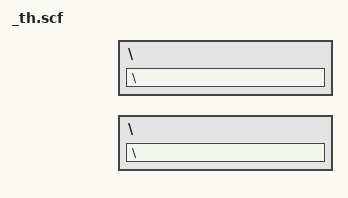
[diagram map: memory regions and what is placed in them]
cfs entry for: _th.fld
doc 0
  field 0
    name titolo
    type string
    value rfc4444.txt
  field 1
    name contenuto
    type string
    value \
\
\
\
\
\
Network Working Group                                     J. Parker, Ed.\
Request for Comments: 4444                             Axiowave Networks\
Category: Standards Track                                     April 2006\
\
\
                    Management Information Base for\
           Intermediate System to Intermediate System (IS-IS)\
\
Status of This Memo\
\
   This document specifies an Internet standards track protocol for the\
   Internet community, and requests discussion and suggestions for\
   improvements.  Please refer to the current edition of the "Internet\
   Official Protocol Standards" (STD 1) for the standardization state\
   and status of this protocol.  Distribution of this memo is unlimited.\
\
Copyright Notice\
\
   Copyright (C) The Internet Society (2006).\
\
Abstract\
\
   This memo defines a portion of the Management Information Base (MIB)\
   for use with network management protocols in the Internet community.\
   Specifically, this document describes a MIB for the Intermediate\
   System to Intermediate System (IS-IS) Routing protocol when it is\
   used to construct routing tables for IP networks.\
\
Table of Contents\
\
   1. The Internet-Standard Management Framework . . . . . . . . . .   2\
   2. Overview . . . . . . . . . . . . . . . . . . . . . . . . . . .   2\
   3. Conventions  . . . . . . . . . . . . . . . . . . . . . . . . .   5\
   4. Definition of IS-IS MIB. . . . . . . . . . . . . . . . . . . .   6\
   5. IANA Considerations. . . . . . . . . . . . . . . . . . . . . .  96\
   6. Acknowledgements . . . . . . . . . . . . . . . . . . . . . . .  96\
   7. Security Considerations. . . . . . . . . . . . . . . . . . . .  96\
   8. Normative References . . . . . . . . . . . . . . . . . . . . . 101\
   9. Informative References . . . . . . . . . . . . . . . . . . . . 102\
\
\
\
\
\
\
\
\
\
\
\
\
Parker                      Standards Track                     [Page 1]\
\
RFC 4444                       IS-IS MIB                      April 2006\
\
\
1.  The Internet-Standard Management Framework\
\
   For a detailed overview of the documents that describe the current\
   Internet-Standard Management Framework, please refer to section 7 of\
   RFC 3410 [RFC3410].\
\
   Managed objects are accessed via a virtual information store, termed\
   the Management Information Base or MIB.  MIB objects are generally\
   accessed through the Simple Network Management Protocol (SNMP).\
   Objects in the MIB are defined using the mechanisms defined in the\
   Structure of Management Information (SMI).  This memo specifies a MIB\
   module that is compliant to the SMIv2, which is described in STD 58,\
   RFC 2578 [RFC2578], STD 58, RFC 2579 [RFC2579] and STD 58, RFC 2580\
   [RFC2580].\
\
2.  Overview\
\
   This document describes a management information base for the\
   Intermediate System to Intermediate System (IS-IS) Routing protocol,\
   as described in ISO 10589 [ISO10589], when it is used to construct\
   routing tables for IP networks, as described in RFC 1195 [RFC1195].\
   The objects are mainly derived from the Guidelines for Definition of\
   Managed Objects (GDMO) definitions in ISO 10589 and from the GDMO\
   definitions in ISO 10733 [ISO10733].  There are also additional\
   objects for managing the IP-specific functionality of Integrated IS-\
   IS operation.\
\
   This MIB imports definitions from SNMPv2-TC [RFC2579], SNMPv2-SMI\
   [RFC2578], SNMPv2-CONF [RFC2580], SNMP-FRAMEWORK-MIB [RFC3411],\
   DIFFSERV-MIB [RFC3289], IF-MIB [RFC2863], and INET-ADDRESS-MIB\
   [RFC4001].  See the imports section of the MIB for the specific items\
   imported.\
\
   This MIB defines some objects to manage Mesh Groups, described in\
   [RFC2973], and a three-way handshake for point-to-point adjacencies,\
   described in [RFC3373].\
\
   The IS-IS MIB defines the following objects:\
\
   System-Wide Attributes\
\
      -  isisSystem\
\
         This table contains information specific to a single instance\
         of the IS-IS protocol running on a router.\
\
\
\
\
\
\
Parker                      Standards Track                     [Page 2]\
\
RFC 4444                       IS-IS MIB                      April 2006\
\
\
      -  isisManAreaAddr\
\
         This table includes area addresses that are manually\
         configured, which are used to control the associations formed\
         between Level 1 Intermediate Systems.\
\
      -  isisAreaAddr\
\
         This table includes area addresses reported in relevant L1\
         LSPs.\
\
      -  isisSummAddr\
\
         This table holds summary addresses configured for each Level 2\
         instance of the IS-IS protocol running on a router.\
\
      -  isisRedistributeAddr\
\
         This table provides criteria to decide whether a route should\
         be leaked from L2 to L1 when Domain Wide Prefix leaking is\
         enabled.\
\
      -  isisRouter\
\
         This table holds the hostname and router ID for Intermediate\
         Systems in the network.\
\
      -  isisSysLevel\
\
         This table contains information specific to a domain (Level 2)\
         or an area (Level 1) of the IS-IS protocol.\
\
      -  isisNextCircIndex\
\
         This scalar is used to provide a unique circuit index.\
\
   Circuit-specific Attributes\
\
      -  isisCirc\
\
         This table contains information specific to a point-to-point or\
         a broadcast interface in the system.\
\
      -  isisCircLevel\
\
         This table contains information specific to Level 1 or Level 2\
         of an interface.\
\
\
\
\
Parker                      Standards Track                     [Page 3]\
\
RFC 4444                       IS-IS MIB                      April 2006\
\
\
   Counters\
\
      -  isisSystemCounter\
\
         Counters in the System table, such as number of times we have\
         wrapped a sequence counter on one of our Link State PDUs.\
\
      -  isisCircuitCounter\
\
         Counters of events particular to a circuit, such as PDUs with\
         an illegal value of the System ID field length.\
\
      -  isisPacketCounter\
\
         Counts of IS-IS Protocol PDUs broken down into packet type.\
\
   Attributes associated with an Adjacency\
\
      -  isisISAdj\
\
         This table contains information about adjacencies to routers\
         maintained by the protocol.  Entries in this table cannot be\
         created by management action: they are established through the\
         Hello protocol.\
\
      -  isisISAdjAreaAddr\
\
         This table contains the set of Area Addresses of neighboring\
         Intermediate Systems, as reported in IIH PDUs.\
\
      -  isisISAdjIPAddr\
\
         This table contains the set of IP Addresses of neighboring\
         Intermediate Systems, as reported in received IIH PDUs.\
\
      -  isisISAdjProtSupp\
\
         This table contains the set of protocols supported by\
         neighboring Intermediate Systems, as reported in received IIH\
         PDUs.\
\
\
\
\
\
\
\
\
\
\
\
Parker                      Standards Track                     [Page 4]\
\
RFC 4444                       IS-IS MIB                      April 2006\
\
\
   Attributes Associated with Addresses\
\
      -  isisRA\
\
         The Reachable Address Table.\
\
         This table contains information about an address prefix\
         manually configured on the system or learned through another\
         protocol.\
\
      -  isisIPRA\
\
         The IP Reachable Address Table.\
\
         This table contains information about an IP reachable address\
         manually configured on this system or learned from another\
         protocol.\
\
   Attributes Associated with Link State PDU Table\
\
      -  isisLSPSummaryTable\
\
         The Link State PDU Summary Table.\
\
         This table contains information contained in the headers of\
         Link State PDUs stored by the system.\
\
      -  isisLSPTLVTable\
\
         The Link State PDU TLV Table.\
\
         This table holds the sequence of TLVs that make up an LSP\
         fragment.\
\
   Attributes Associated with a Notification\
\
      -  isisNotification\
\
         This table defines attributes that will be included when\
         reporting IS-IS notifications.\
\
3.  Conventions\
\
   The key words "MUST", "MUST NOT", "REQUIRED", "SHALL", "SHALL NOT",\
   "SHOULD", "SHOULD NOT", "RECOMMENDED", "NOT RECOMMENDED", "MAY", and\
   "OPTIONAL", when they appear in this document, are to be interpreted\
   as described in BCP 14, RFC 2119 [RFC2119].\
\
\
\
\
Parker                      Standards Track                     [Page 5]\
\
RFC 4444                       IS-IS MIB                      April 2006\
\
\
4.  Definition of IS-IS MIB\
\
ISIS-MIB DEFINITIONS ::= BEGIN\
     IMPORTS\
        TEXTUAL-CONVENTION, RowStatus, TruthValue, TimeStamp\
                FROM SNMPv2-TC               -- RFC2579\
        MODULE-IDENTITY, OBJECT-TYPE, NOTIFICATION-TYPE,\
            Unsigned32, Counter32, mib-2\
                FROM SNMPv2-SMI              -- RFC2578\
        MODULE-COMPLIANCE, OBJECT-GROUP, NOTIFICATION-GROUP\
                FROM SNMPv2-CONF             -- RFC2580\
        SnmpAdminString\
                FROM SNMP-FRAMEWORK-MIB      -- RFC2571\
        IndexInteger, IndexIntegerNextFree\
                FROM DIFFSERV-MIB            -- RFC3289\
        InterfaceIndex\
                FROM IF-MIB                  -- RFC2863\
        InetAddressType, InetAddress, InetAddressPrefixLength\
                FROM INET-ADDRESS-MIB;       -- RFC3291\
\
    isisMIB MODULE-IDENTITY\
        LAST-UPDATED "200604040000Z" -- April 4, 2006, midnight\
        ORGANIZATION "IETF IS-IS for IP Internets Working Group"\
        CONTACT-INFO\
            "IS-IS for IP Internets working Group\
             http://www.ietf.org/html.charters/isis-charter.html\
             isis-wg@ietf.org\
\
             Jeff Parker\
             Department of Computer Science\
             Middlebury College,\
             Middlebury, Vermont 05753\
             jeffp at middlbury dot edu"\
\
        DESCRIPTION\
             "This document describes a management information base for\
             the IS-IS Routing protocol, as described in ISO 10589,\
             when it is used to construct routing tables for IP\
             networks, as described in RFC 1195.\
\
             This document is based on a 1994 IETF document by Chris\
             Gunner.  This version has been modified to include\
             current syntax, to exclude portions of the protocol that\
             are not relevant to IP, and to add management support for\
             current practice.\
\
\
\
\
\
\
Parker                      Standards Track                     [Page 6]\
\
RFC 4444                       IS-IS MIB                      April 2006\
\
\
             Copyright (C) The Internet Society (2006).  This version\
             of this MIB module is part of RFC 4444; see the RFC\
             itself for full legal notices."\
\
        REVISION "200604040000Z" -- April 4, 2006, midnight\
\
        DESCRIPTION\
            "Initial version, published as RFC 4444."\
    ::= { mib-2 138 }\
\
-- Top-level structure of the MIB\
\
isisNotifications       OBJECT IDENTIFIER ::= { isisMIB 0 }\
isisObjects             OBJECT IDENTIFIER ::= { isisMIB 1 }\
isisConformance         OBJECT IDENTIFIER ::= { isisMIB 2 }\
\
-- OBJECT IDENTIFIER definitions\
\
-- System wide attributes.\
isisSystem OBJECT IDENTIFIER ::= { isisObjects 1 }\
\
-- Attributes associated with the domain or with the area.\
isisSysLevel OBJECT IDENTIFIER ::= { isisObjects 2 }\
\
-- Attributes associated with one Circuit\
isisCirc OBJECT IDENTIFIER ::= { isisObjects 3 }\
\
-- Attributes associated with area or domain relevant within a Circuit.\
isisCircLevelValues OBJECT IDENTIFIER ::= { isisObjects 4 }\
\
-- System and circuit counters.\
isisCounters OBJECT IDENTIFIER ::= { isisObjects 5 }\
\
-- Attributes associated with an adjacent Protocol Peer.\
isisISAdj OBJECT IDENTIFIER ::= { isisObjects 6 }\
\
-- Attributes associated with a configured address.\
isisReachAddr OBJECT IDENTIFIER ::= { isisObjects 7 }\
\
-- Attributes associated with IP routes learned by\
-- configuration or through another protocol.\
isisIPReachAddr OBJECT IDENTIFIER ::= { isisObjects 8 }\
\
-- The collection of Link State PDUs known to the Intermediate System\
isisLSPDataBase OBJECT IDENTIFIER ::= { isisObjects 9 }\
\
-- Objects included in Notifications.\
isisNotification OBJECT IDENTIFIER ::= { isisObjects 10 }\
\
\
\
Parker                      Standards Track                     [Page 7]\
\
RFC 4444                       IS-IS MIB                      April 2006\
\
\
-- Type definitions\
\
    IsisOSINSAddress ::= TEXTUAL-CONVENTION\
        STATUS current\
        DESCRIPTION\
            "OSI Network Service Address, e.g., NSAP, SNPA, or Network\
             Entity Title"\
        SYNTAX OCTET STRING (SIZE(0..20))\
\
    IsisSystemID ::= TEXTUAL-CONVENTION\
        STATUS current\
        DESCRIPTION\
            "The ID for an Intermediate System.  This should\
             be unique within a network, and is included\
             in all PDUs originated by an Intermediate System.\
             The protocol does not place any meanings upon\
             the bits, other than using ordering to break\
             ties in electing a Designated IS on a LAN."\
        REFERENCE "{ISIS.aoi systemId (119)}"\
        SYNTAX OCTET STRING (SIZE(6))\
\
    IsisLinkStatePDUID ::= TEXTUAL-CONVENTION\
        STATUS current\
        DESCRIPTION\
            "The 8-byte Link State PDU (LSP) ID,\
             consisting of the 6-byte SystemID of the\
             originating IS; a one-byte PseudoNode ID,\
             which is 0 unless the LSP represents the\
             topology of a LAN; and a one-byte LSP\
             fragment number that is issued in sequence,\
             starting with 0.  Non-zero PseudoNode IDs\
             need to be unique to the IS but need not\
             match the IfIndex."\
        REFERENCE "{See section 9.8 of ISO 10589}"\
        SYNTAX OCTET STRING (SIZE(8))\
\
    IsisAdminState ::= TEXTUAL-CONVENTION\
        STATUS current\
        DESCRIPTION\
            "Type used in enabling and disabling a row."\
        SYNTAX INTEGER\
            {\
                on(1),\
                off(2)\
            }\
\
    IsisLSPBuffSize ::= TEXTUAL-CONVENTION\
        DISPLAY-HINT "d"\
\
\
\
Parker                      Standards Track                     [Page 8]\
\
RFC 4444                       IS-IS MIB                      April 2006\
\
\
        STATUS current\
        DESCRIPTION\
            "Integer sub-range for maximum LSP size."\
        SYNTAX Unsigned32 (512..16000)\
\
    IsisLevelState ::= TEXTUAL-CONVENTION\
        STATUS current\
        DESCRIPTION\
            "States of the IS-IS protocol."\
        SYNTAX INTEGER\
            {\
                off (1),\
                on (2),\
                waiting (3),\
                overloaded(4)\
            }\
\
    IsisSupportedProtocol ::= TEXTUAL-CONVENTION\
        STATUS current\
        DESCRIPTION\
            "Types of network protocol supported by Integrated IS-IS.\
             The values for ISO8473 and IP are those registered for\
             these protocols in ISO TR9577."\
        REFERENCE "{See section 5.3.1 of RFC 1195}"\
        SYNTAX INTEGER\
            {\
                iso8473(129),\
                ipV6(142),\
                ip(204)\
            }\
\
    IsisDefaultMetric ::= TEXTUAL-CONVENTION\
        DISPLAY-HINT "d"\
        STATUS current\
        DESCRIPTION\
            "Integer sub-range for default metric for single hop.\
             ISO 10589 provides for 4 types of metric.  Only the\
             'default' metric is used in practice."\
        REFERENCE "{See section 7.2.2 of ISO 10589}"\
        SYNTAX Unsigned32 (0..63)\
\
    IsisWideMetric ::= TEXTUAL-CONVENTION\
        DISPLAY-HINT "d"\
        STATUS current\
        DESCRIPTION\
            "Wide metric for IS Neighbors.  ISO 10589 provides a\
             6-bit metric.  Traffic Engineering extensions provide\
             24-bit metrics."\
\
\
\
Parker                      Standards Track                     [Page 9]\
\
RFC 4444                       IS-IS MIB                      April 2006\
\
\
        REFERENCE "{See section 3 of RFC 3784}"\
        SYNTAX Unsigned32 (0..16777215)\
\
    IsisFullMetric ::= TEXTUAL-CONVENTION\
        DISPLAY-HINT "d"\
        STATUS current\
        DESCRIPTION\
            "Full metric for IP Routes.  Traffic Engineering extensions\
             provide 32-bit metrics."\
        REFERENCE "{See section 4 of RFC 3784}"\
        SYNTAX Unsigned32\
\
    IsisMetricType ::= TEXTUAL-CONVENTION\
        STATUS current\
        DESCRIPTION\
            "Is this an Internal or External Metric?"\
        REFERENCE "{See section 7.2.2 of ISO 10589}"\
        SYNTAX INTEGER\
            {\
                internal(1),\
                external(2)\
            }\
\
    IsisMetricStyle ::= TEXTUAL-CONVENTION\
        STATUS current\
        DESCRIPTION\
            "Do we use RFC 1195 style metrics or wide metrics?"\
        REFERENCE "{See section 5 of RFC 3787}"\
        SYNTAX INTEGER\
            {\
                narrow(1),\
                wide(2),\
                both(3)\
            }\
\
    IsisISLevel ::= TEXTUAL-CONVENTION\
        STATUS current\
        DESCRIPTION\
            "Identifies a level."\
        REFERENCE "{See definitions 3.6.1 and 3.6.11 of ISO 10589}"\
        SYNTAX INTEGER\
            {\
                area(1),        -- L1\
                domain(2)       -- L2\
            }\
\
    IsisLevel ::= TEXTUAL-CONVENTION\
        STATUS current\
\
\
\
Parker                      Standards Track                    [Page 10]\
\
RFC 4444                       IS-IS MIB                      April 2006\
\
\
        DESCRIPTION\
            "Identifies one or more levels."\
        REFERENCE "{See definitions 3.6.1 and 3.6.11 of ISO 10589}"\
        SYNTAX INTEGER\
            {\
                level1(1),\
                level2(2),\
                level1and2(3)\
            }\
\
    IsisPDUHeader ::= TEXTUAL-CONVENTION\
        STATUS current\
        DESCRIPTION\
            "A block to contain the header from a PDU."\
        SYNTAX OCTET STRING (SIZE(0..64))\
\
    IsisCircuitID ::= TEXTUAL-CONVENTION\
        STATUS current\
        DESCRIPTION\
            "ID for a circuit."\
        REFERENCE "{See section 7.2.7 of ISO 10589}"\
        SYNTAX OCTET STRING (SIZE(0|7))\
\
    IsisISPriority ::= TEXTUAL-CONVENTION\
        DISPLAY-HINT "d"\
        STATUS current\
        DESCRIPTION\
            "Integer sub-range for IS-IS priority."\
        REFERENCE "{See section 9.5 of ISO 10589}"\
        SYNTAX Unsigned32 (0..127)\
\
    IsisUnsigned16TC ::= TEXTUAL-CONVENTION\
        DISPLAY-HINT "d"\
        STATUS current\
        DESCRIPTION\
            "An Unsigned32 further restricted to 16 bits.  Note that\
             the ASN.1 BER encoding may still require 24 bits for\
             some values."\
        SYNTAX Unsigned32 (0..65535)\
\
    IsisUnsigned8TC ::= TEXTUAL-CONVENTION\
        DISPLAY-HINT "d"\
        STATUS current\
        DESCRIPTION\
            "An Unsigned32 further restricted to 8 bits.  Note that\
             the ASN.1 BER encoding may still require 16 bits for\
             some values."\
        SYNTAX Unsigned32 (0..255)\
\
\
\
Parker                      Standards Track                    [Page 11]\
\
RFC 4444                       IS-IS MIB                      April 2006\
\
\
-- Behavior Definitions\
\
-- ResettingTimer behavior definition\
--\
\
-- "This behavior applies to objects that specify the interval\
-- between events in the operation of the protocol state machine.\
-- If the value of such an object is set to a new value while\
-- the protocol state machine is in operation, the implementation\
-- shall take the necessary steps to ensure that for any time\
-- interval that was in progress when the value of the\
-- corresponding object was changed, the next expiration of that\
-- interval takes place the specified time after the original\
-- start of that interval, or immediately, whichever is later.\
-- The precision with which this time shall be implemented shall\
-- be the same as that associated with the basic operation of\
-- the timer object."\
\
-- ReplaceOnlyWhileDisabled behavior definition\
-- "This behavior applies to objects that may not be modified\
-- while the corresponding table row's variable of type\
-- IsisAdminState is in state on."\
\
-- ManualOrAutomatic behavior definition\
-- "This behavior applies to objects that are read-write\
-- if the object was created manually.  Objects that were\
-- created automatically that have this behavior are\
-- read-only.\
\
    isisSysObject  OBJECT IDENTIFIER ::= { isisSystem 1 }\
\
    isisSysVersion OBJECT-TYPE\
        SYNTAX INTEGER\
            {\
                unknown(0),\
                one(1)\
            }\
        MAX-ACCESS read-only\
        STATUS current\
        DESCRIPTION\
            "The version number of the IS-IS protocol that\
             is implemented."\
        REFERENCE "{ISIS.aoi version (1)}"\
        DEFVAL { one }\
    ::= { isisSysObject 1 }\
\
    isisSysLevelType OBJECT-TYPE\
        SYNTAX IsisLevel\
\
\
\
Parker                      Standards Track                    [Page 12]\
\
RFC 4444                       IS-IS MIB                      April 2006\
\
\
        MAX-ACCESS read-write\
        STATUS current\
        DESCRIPTION\
            "At which levels is the Intermediate System\
             running? This object may not be modified when\
             the isisSysAdminState variable is in state 'on'\
             for this Intermediate System.\
\
             Configured values MUST survive an agent reboot."\
        REFERENCE "{ISIS.aoi iSType (2)}"\
        DEFVAL { level1and2 }\
    ::= { isisSysObject 2 }\
\
    isisSysID OBJECT-TYPE\
        SYNTAX IsisSystemID\
        MAX-ACCESS read-write\
        STATUS current\
        DESCRIPTION\
            "The ID for this Intermediate System.\
             This value is appended to each of the\
             area addresses to form the Network Entity Titles.\
             The derivation of a value for this object is\
             implementation specific.  Some implementations may\
             automatically assign values and not permit an\
             SNMP write, while others may require the value\
             to be set manually.\
\
             Configured values MUST survive an agent reboot."\
        REFERENCE "{ISIS.aoi systemId (119)}"\
    ::= { isisSysObject 3 }\
\
    isisSysMaxPathSplits OBJECT-TYPE\
        SYNTAX Unsigned32 (1..32)\
        MAX-ACCESS read-write\
        STATUS current\
        DESCRIPTION\
            "Maximum number of paths with equal routing metric value\
             which it is permitted to split between.  This object\
             may not be modified when the isisSysAdminState variable\
             is in state 'on' for this Intermediate System.\
\
             Configured values MUST survive an agent reboot."\
        REFERENCE "{ISIS.aoi maximumPathSplits (3)}"\
        DEFVAL { 2 }\
    ::= { isisSysObject 4 }\
\
    isisSysMaxLSPGenInt OBJECT-TYPE\
        SYNTAX Unsigned32 (1..65235)\
\
\
\
Parker                      Standards Track                    [Page 13]\
\
RFC 4444                       IS-IS MIB                      April 2006\
\
\
        UNITS "seconds"\
        MAX-ACCESS read-write\
        STATUS current\
        DESCRIPTION\
            "Maximum interval, in seconds, between generated LSPs\
             by this Intermediate System.  This object follows\
             the ResettingTimer behavior.  The value must be\
             greater than any value configured for\
             isisSysLevelMinLSPGenInt, and should be at least 300\
             seconds less than isisSysMaxAge.\
\
             Configured values MUST survive an agent reboot."\
        REFERENCE "{ISIS.aoi maximumLSPGenerationInterval (6)}"\
        DEFVAL { 900 }\
    ::= { isisSysObject 5 }\
\
    isisSysPollESHelloRate OBJECT-TYPE\
        SYNTAX IsisUnsigned16TC (1..65535)\
        UNITS "seconds"\
        MAX-ACCESS read-write\
        STATUS current\
        DESCRIPTION\
            "The value, in seconds, to be used for the suggested ES\
             configuration timer in ISH PDUs when soliciting the ES\
             configuration.\
\
             Configured values MUST survive an agent reboot."\
        REFERENCE "{ISIS.aoi pollESHelloRate (13)}"\
        DEFVAL { 50 }\
    ::= { isisSysObject 6 }\
\
    isisSysWaitTime OBJECT-TYPE\
        SYNTAX IsisUnsigned16TC (1..65535)\
        UNITS "seconds"\
        MAX-ACCESS read-write\
        STATUS current\
        DESCRIPTION\
            "Number of seconds to delay in state 'waiting' before\
             entering the state 'on'.  This object follows the\
             ResettingTimer behavior.\
\
             Configured values MUST survive an agent reboot."\
        REFERENCE "{ISIS.aoi waitingTime (15)}"\
        DEFVAL { 60 }\
    ::= { isisSysObject 7 }\
\
    isisSysAdminState OBJECT-TYPE\
        SYNTAX IsisAdminState\
\
\
\
Parker                      Standards Track                    [Page 14]\
\
RFC 4444                       IS-IS MIB                      April 2006\
\
\
        MAX-ACCESS read-write\
        STATUS current\
        DESCRIPTION\
            "The administrative state of this Intermediate\
             System.  Setting this object to the value 'on'\
             when its current value is 'off' enables\
             the Intermediate System.\
\
             Configured values MUST survive an agent reboot."\
        DEFVAL { off }\
    ::= { isisSysObject 8 }\
\
    isisSysL2toL1Leaking OBJECT-TYPE\
        SYNTAX TruthValue\
        MAX-ACCESS read-write\
        STATUS current\
        DESCRIPTION\
            "If true, allow the router to leak L2 routes into L1.\
\
             Configured values MUST survive an agent reboot."\
        DEFVAL { false }\
    ::= { isisSysObject 9 }\
\
    isisSysMaxAge OBJECT-TYPE\
        SYNTAX IsisUnsigned16TC (350..65535)\
        UNITS "seconds"\
        MAX-ACCESS read-write\
        STATUS current\
        DESCRIPTION\
            "Value to place in RemainingLifeTime field of\
             the LSPs we generate.\
             This should be at least 300 seconds greater than\
             isisSysMaxLSPGenInt.\
\
             Configured values MUST survive an agent reboot."\
        DEFVAL { 1200 }\
    ::= { isisSysObject 10 }\
\
    isisSysReceiveLSPBufferSize OBJECT-TYPE\
        SYNTAX IsisUnsigned16TC (1492..16000)\
        UNITS "bytes"\
        MAX-ACCESS read-write\
        STATUS current\
        DESCRIPTION\
            "Size of the largest buffer we are designed or\
             configured to store.  This should be at least\
             as big as the maximum isisSysLevelOrigLSPBuffSize\
             supported by the system.\
\
\
\
Parker                      Standards Track                    [Page 15]\
\
RFC 4444                       IS-IS MIB                      April 2006\
\
\
             If resources allow, we will store and flood LSPs\
             larger than isisSysReceiveLSPBufferSize, as this\
             can help avoid problems in networks with different\
             values for isisSysLevelOrigLSPBuffSize.\
\
             Configured values MUST survive an agent reboot."\
        DEFVAL { 1492 }\
    ::= { isisSysObject 11 }\
\
    isisSysProtSupported OBJECT-TYPE\
        SYNTAX BITS {\
                    iso8473 (0),\
                    ipv4 (1),\
                    ipv6 (2)\
                  }\
        MAX-ACCESS read-only\
        STATUS current\
        DESCRIPTION\
            "This attribute contains the set of protocols\
             supported by this Intermediate System."\
    ::= { isisSysObject 12 }\
\
    isisSysNotificationEnable OBJECT-TYPE\
        SYNTAX TruthValue\
        MAX-ACCESS read-write\
        STATUS current\
        DESCRIPTION\
            "If this object is set to true(1), then it enables\
             the emission of IS-IS Notifications.  If it is\
             set to false(2), these notifications are not sent.\
\
             Configured values MUST survive an agent reboot."\
        DEFVAL { true }\
    ::= { isisSysObject 13 }\
\
-- The Level 1 Manual Area Address Table\
\
    isisManAreaAddrTable OBJECT-TYPE\
        SYNTAX SEQUENCE OF IsisManAreaAddrEntry\
        MAX-ACCESS not-accessible\
        STATUS current\
        DESCRIPTION\
            "The set of manual area addresses configured on this\
             Intermediate System.\
\
             At least one row in which the value of\
             isisManAreaAddrExistState is active must be present.\
             The maximum number of rows in this table for\
\
\
\
Parker                      Standards Track                    [Page 16]\
\
RFC 4444                       IS-IS MIB                      April 2006\
\
\
             which the object isisManAreaAddrExistState has the\
             value active is 3.\
\
             An attempt to create more than 3 rows of\
             isisManAreaAddrEntry with state 'active' in one\
             instance of the IS-IS protocol should\
             return inconsistentValue."\
        REFERENCE "{ISIS.aoi manualAreaAddresses (10)}"\
    ::= { isisSystem 2 }\
\
    isisManAreaAddrEntry OBJECT-TYPE\
        SYNTAX IsisManAreaAddrEntry\
        MAX-ACCESS not-accessible\
        STATUS current\
        DESCRIPTION\
            "Each entry contains one area address manually configured\
             on this system.\
\
             Dynamically created rows MUST survive an agent reboot."\
        INDEX { isisManAreaAddr }\
    ::= { isisManAreaAddrTable 1 }\
\
    IsisManAreaAddrEntry ::=\
        SEQUENCE {\
            isisManAreaAddr\
                IsisOSINSAddress,\
            isisManAreaAddrExistState\
                RowStatus\
            }\
\
    isisManAreaAddr OBJECT-TYPE\
        SYNTAX IsisOSINSAddress\
        MAX-ACCESS not-accessible\
        STATUS current\
        DESCRIPTION\
            "A manually configured area address for this system.\
\
             Note: An index for the entry {1, {49.0001} active} in\
             this table would be the ordered pair\
             (1, (0x03 0x49 0x00 0x01)), as the length of an octet\
             string is part of the OID."\
    ::= { isisManAreaAddrEntry 1 }\
\
    isisManAreaAddrExistState OBJECT-TYPE\
        SYNTAX RowStatus\
        MAX-ACCESS read-create\
        STATUS current\
        DESCRIPTION\
\
\
\
Parker                      Standards Track                    [Page 17]\
\
RFC 4444                       IS-IS MIB                      April 2006\
\
\
            "The state of the isisManAreaAddrEntry.  If the\
             isisSysAdminState for this Intermediate System is 'on' and\
             an attempt is made to set this object to the value\
             'destroy' or 'notInService' when this is the only\
             isisManAreaAddrEntry in state 'active' for this\
             Intermediate System should return inconsistentValue.\
\
             A row entry cannot be modified when the value of this\
             object is 'active'."\
    ::= { isisManAreaAddrEntry 2 }\
\
-- The Level 1 Area Address Table\
\
-- The Level 1 Area Address Table contains the\
-- union of the sets of relevant area addresses configured\
-- or learned from Level 1 LSPs received by this Intermediate System.\
\
    isisAreaAddrTable OBJECT-TYPE\
        SYNTAX SEQUENCE OF IsisAreaAddrEntry\
        MAX-ACCESS not-accessible\
        STATUS current\
        DESCRIPTION\
            "The union of the sets of area addresses reported in all\
             Level 1 LSPs with fragment number zero generated by this\
             Intermediate System, or received from other Intermediate\
             Systems that are reachable via Level 1 routing."\
        REFERENCE "{ISIS.aoi areaAddresses (18)}"\
    ::= { isisSystem 3 }\
\
    isisAreaAddrEntry OBJECT-TYPE\
        SYNTAX IsisAreaAddrEntry\
        MAX-ACCESS not-accessible\
        STATUS current\
        DESCRIPTION\
            "Each entry contains one area address reported in a\
             Level 1 LSP generated or received by this Intermediate\
             System.\
\
             Dynamically learned rows do not survive an agent reboot."\
        INDEX { isisAreaAddr }\
    ::= { isisAreaAddrTable 1 }\
\
    IsisAreaAddrEntry ::=\
        SEQUENCE {\
            isisAreaAddr\
                IsisOSINSAddress\
            }\
\
\
\
\
Parker                      Standards Track                    [Page 18]\
\
RFC 4444                       IS-IS MIB                      April 2006\
\
\
    isisAreaAddr OBJECT-TYPE\
        SYNTAX IsisOSINSAddress\
        MAX-ACCESS read-only\
        STATUS current\
        DESCRIPTION\
            "An area address reported in a Level 1 LSP."\
    ::= { isisAreaAddrEntry 1 }\
\
-- The Summary Address Table\
\
-- The Summary Address Table contains the set of summary\
-- addresses manually configured for the Intermediate System.\
--\
-- This is used to control leaking L1 routes into L2.\
\
    isisSummAddrTable OBJECT-TYPE\
        SYNTAX SEQUENCE OF IsisSummAddrEntry\
        MAX-ACCESS not-accessible\
        STATUS current\
        DESCRIPTION\
            "The set of IP summary addresses to use in forming\
             summary TLVs originated by this Intermediate System.\
\
             An administrator may use a summary address to combine\
             and modify IP Reachability announcements.  If the\
             Intermediate system can reach any subset of the summary\
             address, the summary address MUST be announced instead,\
             at the configured metric."\
    ::= { isisSystem 4 }\
\
    isisSummAddrEntry OBJECT-TYPE\
        SYNTAX IsisSummAddrEntry\
        MAX-ACCESS not-accessible\
        STATUS current\
        DESCRIPTION\
            "Each entry contains one IP summary address.\
\
             Dynamically created rows MUST survive an agent reboot.\
\
             Implementers need to be aware that if the total number\
             of elements (octets or sub-identifiers) in\
             isisSummAddress and isisSummAddrPrefixLen is too great,\
             then OIDs of column instances in this table will have\
             more than 128 subidentifiers and cannot be accessed\
             using SNMPv1, SNMPv2c, or SNMPv3."\
        INDEX { isisSummAddressType,\
                isisSummAddress,\
                isisSummAddrPrefixLen }\
\
\
\
Parker                      Standards Track                    [Page 19]\
\
RFC 4444                       IS-IS MIB                      April 2006\
\
\
    ::= { isisSummAddrTable 1 }\
\
    IsisSummAddrEntry ::=\
        SEQUENCE {\
            isisSummAddressType\
                InetAddressType,\
            isisSummAddress\
                InetAddress,\
            isisSummAddrPrefixLen\
                InetAddressPrefixLength,\
            isisSummAddrExistState\
                RowStatus,\
            isisSummAddrMetric\
                IsisDefaultMetric,\
            isisSummAddrFullMetric\
                IsisFullMetric\
        }\
\
    isisSummAddressType OBJECT-TYPE\
        SYNTAX InetAddressType\
        MAX-ACCESS not-accessible\
        STATUS current\
        DESCRIPTION\
            "The Type of IP address for this summary address."\
    ::= { isisSummAddrEntry 1 }\
\
    isisSummAddress OBJECT-TYPE\
        SYNTAX InetAddress\
        MAX-ACCESS not-accessible\
        STATUS current\
        DESCRIPTION\
            "The IP Address value for this summary address.\
             The address must not contain any set host bits\
             (bits set after the address prefix determined by\
             isisSummAddrPrefixLen).\
\
             The type of this address is determined by the value of\
             the isisSummAddressType object."\
    ::= { isisSummAddrEntry 2 }\
\
    isisSummAddrPrefixLen OBJECT-TYPE\
        SYNTAX InetAddressPrefixLength\
        MAX-ACCESS not-accessible\
        STATUS current\
        DESCRIPTION\
            "The Length of the IP NetMask for this summary address.\
\
             The values for the index objects isisSummAddress and\
\
\
\
Parker                      Standards Track                    [Page 20]\
\
RFC 4444                       IS-IS MIB                      April 2006\
\
\
             isisSummAddrPrefixLen must be consistent.  When the value\
             of isisSummAddress (excluding the zone index, if one\
             is present) is x, then the bitwise logical-AND\
             of x with the value of the mask formed from the\
             corresponding index object isisSummAddrPrefixLen MUST be\
             equal to x.  If not, then the index pair is not\
             consistent, and an inconsistentName error must be\
             returned on SET or CREATE requests."\
    ::= { isisSummAddrEntry 3 }\
\
    isisSummAddrExistState OBJECT-TYPE\
        SYNTAX RowStatus\
        MAX-ACCESS read-create\
        STATUS current\
        DESCRIPTION\
            "The existence state of this summary address.  Support\
             for 'createAndWait' and 'notInService' is not required.\
\
             A row entry cannot be modified when the value of this\
             object is 'active'."\
    ::= { isisSummAddrEntry 4 }\
\
    isisSummAddrMetric OBJECT-TYPE\
        SYNTAX IsisDefaultMetric\
        MAX-ACCESS read-create\
        STATUS current\
        DESCRIPTION\
            "The metric value to announce this summary\
             address within LSPs generated by this system."\
        DEFVAL { 20 }\
    ::= { isisSummAddrEntry 5 }\
\
    isisSummAddrFullMetric OBJECT-TYPE\
        SYNTAX IsisFullMetric\
        MAX-ACCESS read-create\
        STATUS current\
        DESCRIPTION\
            "The wide metric value to announce this summary\
             address within LSPs generated by this system."\
        DEFVAL { 20 }\
    ::= { isisSummAddrEntry 6 }\
\
-- The Redistribution table defines addresses that should be\
-- leaked from L2 to L1 if isisSysL2toL1Leaking is enabled.\
\
    isisRedistributeAddrTable OBJECT-TYPE\
        SYNTAX SEQUENCE OF IsisRedistributeAddrEntry\
        MAX-ACCESS not-accessible\
\
\
\
Parker                      Standards Track                    [Page 21]\
\
RFC 4444                       IS-IS MIB                      April 2006\
\
\
        STATUS current\
        DESCRIPTION\
            "This table provides criteria to decide if a route should\
             be leaked from L2 to L1 when Domain Wide Prefix leaking is\
             enabled.\
\
             Addresses that match the summary mask in the table MUST\
             be announced at L1 by routers when isisSysL2toL1Leaking\
             is enabled.  Routes that fall into the ranges specified\
             are announced as is, without being summarized.  Routes\
             that do not match a summary mask are not announced."\
    ::= { isisSystem 5 }\
\
    isisRedistributeAddrEntry OBJECT-TYPE\
        SYNTAX IsisRedistributeAddrEntry\
        MAX-ACCESS not-accessible\
        STATUS current\
        DESCRIPTION\
            "Each entry contains one configured IP summary\
             address to manage leaking L2 addresses into L1.\
\
             Dynamically created rows MUST survive an agent reboot.\
\
             Implementers need to be aware that if the total number\
             of elements (octets or sub-identifiers) in\
             isisRedistributeAddrAddress and\
             isisRedistributeAddrPrefixLen is too great, then OIDs\
             of column instances in this table will have more than\
             128 subidentifiers and cannot be accessed using SNMPv1,\
             SNMPv2c, or SNMPv3."\
        INDEX { isisRedistributeAddrType,\
                isisRedistributeAddrAddress,\
                isisRedistributeAddrPrefixLen }\
    ::= { isisRedistributeAddrTable 1 }\
\
    IsisRedistributeAddrEntry ::=\
        SEQUENCE {\
            isisRedistributeAddrType\
                InetAddressType,\
            isisRedistributeAddrAddress\
                InetAddress,\
            isisRedistributeAddrPrefixLen\
                InetAddressPrefixLength,\
            isisRedistributeAddrExistState\
                RowStatus\
        }\
\
    isisRedistributeAddrType OBJECT-TYPE\
\
\
\
Parker                      Standards Track                    [Page 22]\
\
RFC 4444                       IS-IS MIB                      April 2006\
\
\
        SYNTAX InetAddressType\
        MAX-ACCESS not-accessible\
        STATUS current\
        DESCRIPTION\
            "The Type of IP address for this summary address."\
    ::= { isisRedistributeAddrEntry 1 }\
\
    isisRedistributeAddrAddress OBJECT-TYPE\
        SYNTAX InetAddress\
        MAX-ACCESS not-accessible\
        STATUS current\
        DESCRIPTION\
            "The IP Address value for this summary address.\
             The type of this address is determined by the\
             value of the isisRedistributeAddrType object.\
             The address must not contain any set host bits -\
             bits set after the address prefix determined by\
             isisRedistributeAddrPrefixLen."\
\
    ::= { isisRedistributeAddrEntry 2 }\
\
    isisRedistributeAddrPrefixLen OBJECT-TYPE\
        SYNTAX InetAddressPrefixLength\
        MAX-ACCESS not-accessible\
        STATUS current\
        DESCRIPTION\
            "The Length of the IP NetMask for this summary address.\
\
             The values for the index objects\
             isisRedistributeAddrAddress and\
             isisRedistributeAddrPrefixLen must be consistent.\
             When the value of isisRedistributeAddrAddress\
             (excluding the zone index, if one is present) is x,\
             then the bitwise logical-AND of x with the value of\
             the mask formed from the corresponding index object\
             isisRedistributeAddrPrefixLen MUST be equal to x.\
             If not, then the index pair is not consistent, and an\
             inconsistentName error must be returned on SET or\
             CREATE requests."\
\
    ::= { isisRedistributeAddrEntry 3 }\
\
    isisRedistributeAddrExistState OBJECT-TYPE\
        SYNTAX RowStatus\
        MAX-ACCESS read-create\
        STATUS current\
        DESCRIPTION\
            "The existence state of this summary address.  Support\
\
\
\
Parker                      Standards Track                    [Page 23]\
\
RFC 4444                       IS-IS MIB                      April 2006\
\
\
             for createAndWait and notInService is not required.\
\
             A row entry cannot be modified when the value of this\
             object is 'active'."\
    ::= { isisRedistributeAddrEntry 4 }\
\
-- The Router Table keeps track of hostnames and router IDs\
-- associated with Intermediate Systems in the area and domain.\
\
    isisRouterTable OBJECT-TYPE\
        SYNTAX SEQUENCE OF IsisRouterEntry\
        MAX-ACCESS not-accessible\
        STATUS current\
        DESCRIPTION\
            "The set of hostnames and router ID."\
    ::= { isisSystem 6 }\
\
    isisRouterEntry OBJECT-TYPE\
        SYNTAX IsisRouterEntry\
        MAX-ACCESS not-accessible\
        STATUS current\
        DESCRIPTION\
            "Each entry tracks information about one Intermediate\
             System at one level.\
\
             Dynamically learned rows do not survive an agent reboot."\
        INDEX { isisRouterSysID,\
                isisRouterLevel }\
    ::= { isisRouterTable 1 }\
\
    IsisRouterEntry ::=\
        SEQUENCE {\
            isisRouterSysID\
                IsisSystemID,\
            isisRouterLevel\
                IsisISLevel,\
            isisRouterHostName\
                SnmpAdminString,\
            isisRouterID\
                Unsigned32\
        }\
\
    isisRouterSysID OBJECT-TYPE\
        SYNTAX IsisSystemID\
        MAX-ACCESS not-accessible\
        STATUS current\
        DESCRIPTION\
            "The System ID of the Intermediate System."\
\
\
\
Parker                      Standards Track                    [Page 24]\
\
RFC 4444                       IS-IS MIB                      April 2006\
\
\
    ::= { isisRouterEntry 1 }\
\
    isisRouterLevel OBJECT-TYPE\
        SYNTAX IsisISLevel\
        MAX-ACCESS not-accessible\
        STATUS current\
        DESCRIPTION\
            "The level at which the information about this\
             Intermediate System was received."\
    ::= { isisRouterEntry 2 }\
\
    isisRouterHostName OBJECT-TYPE\
        SYNTAX SnmpAdminString\
        MAX-ACCESS read-only\
        STATUS current\
        DESCRIPTION\
            "The hostname listed in the LSP, or a zero-length\
             string if none."\
    ::= { isisRouterEntry 3 }\
\
    isisRouterID OBJECT-TYPE\
        SYNTAX Unsigned32\
        MAX-ACCESS read-only\
        STATUS current\
        DESCRIPTION\
            "The Router ID found in the LSP, or zero if none."\
    ::= { isisRouterEntry 4 }\
\
-- The System Level Table\
-- This table captures level-specific information about the system\
\
    isisSysLevelTable OBJECT-TYPE\
        SYNTAX SEQUENCE OF IsisSysLevelEntry\
        MAX-ACCESS not-accessible\
        STATUS current\
        DESCRIPTION\
            "Level specific information about the System."\
    ::= { isisSysLevel 1 }\
\
    isisSysLevelEntry OBJECT-TYPE\
        SYNTAX IsisSysLevelEntry\
        MAX-ACCESS not-accessible\
        STATUS current\
        DESCRIPTION\
            "Each row describes variables configured for Area or Domain.\
\
             Configured values MUST survive an agent reboot."\
        INDEX { isisSysLevelIndex }\
\
\
\
Parker                      Standards Track                    [Page 25]\
\
RFC 4444                       IS-IS MIB                      April 2006\
\
\
    ::= { isisSysLevelTable 1 }\
\
    IsisSysLevelEntry ::=\
        SEQUENCE {\
            isisSysLevelIndex\
                IsisISLevel,\
            isisSysLevelOrigLSPBuffSize\
                IsisLSPBuffSize,\
            isisSysLevelMinLSPGenInt\
                IsisUnsigned16TC,\
            isisSysLevelState\
                IsisLevelState,\
            isisSysLevelSetOverload\
                TruthValue,\
            isisSysLevelSetOverloadUntil\
                Unsigned32,\
            isisSysLevelMetricStyle\
                IsisMetricStyle,\
            isisSysLevelSPFConsiders\
                IsisMetricStyle,\
            isisSysLevelTEEnabled\
                TruthValue\
        }\
\
    isisSysLevelIndex OBJECT-TYPE\
        SYNTAX IsisISLevel\
        MAX-ACCESS not-accessible\
        STATUS current\
        DESCRIPTION\
            "The level that this entry describes."\
    ::= { isisSysLevelEntry 1 }\
\
    isisSysLevelOrigLSPBuffSize OBJECT-TYPE\
        SYNTAX IsisLSPBuffSize\
        MAX-ACCESS read-write\
        STATUS current\
        DESCRIPTION\
            "The maximum size of LSPs and SNPs originated by\
             this Intermediate System at this level.  This\
             object may not be modified when the isisSysAdminState\
             variable is in state 'on' for this Intermediate System."\
        REFERENCE "{ISIS.aoi originatingL1LSPBufferSize (9)}"\
        DEFVAL { 1492 }\
    ::= { isisSysLevelEntry 2 }\
\
    isisSysLevelMinLSPGenInt OBJECT-TYPE\
        SYNTAX IsisUnsigned16TC (1..65535)\
        UNITS "seconds"\
\
\
\
Parker                      Standards Track                    [Page 26]\
\
RFC 4444                       IS-IS MIB                      April 2006\
\
\
        MAX-ACCESS read-write\
        STATUS current\
        DESCRIPTION\
            "Minimum interval, in seconds, between successive\
             generation of LSPs with the same LSPID at this level\
             by this Intermediate System."\
        REFERENCE "{ISIS.aoi minimumLSPGenerationInterval (11)}"\
        DEFVAL { 30 }\
    ::= { isisSysLevelEntry 3 }\
\
    isisSysLevelState OBJECT-TYPE\
        SYNTAX IsisLevelState\
        MAX-ACCESS read-only\
        STATUS current\
        DESCRIPTION\
            "The state of the database at this level.\
             The value 'off' indicates that IS-IS is not active at\
             this level.\
             The value 'on' indicates that IS-IS is active at this\
             level and is not overloaded.\
             The value 'waiting' indicates a database that is low on\
             an essential resource, such as memory.\
             The administrator may force the state to 'overloaded'\
             by setting the object isisSysLevelSetOverload.\
             If the state is 'waiting' or 'overloaded', we\
             originate LSPs with the overload bit set."\
        REFERENCE "{ISIS.aoi l1State (17)}"\
    ::= { isisSysLevelEntry 4 }\
\
    isisSysLevelSetOverload OBJECT-TYPE\
        SYNTAX TruthValue\
        MAX-ACCESS read-write\
        STATUS current\
        DESCRIPTION\
            "Administratively set the overload bit for the level.\
             The overload bit MUST continue to be set if the\
             implementation runs out of memory, independent of\
             this variable.  It may also be set manually independent\
             of this variable, using the isisSysLevelSetOverloadUntil\
             object."\
        DEFVAL { false }\
    ::= { isisSysLevelEntry 5 }\
\
    isisSysLevelSetOverloadUntil OBJECT-TYPE\
        SYNTAX Unsigned32\
        UNITS "Seconds until clearing manually set Overload Bit"\
        MAX-ACCESS read-write\
        STATUS current\
\
\
\
Parker                      Standards Track                    [Page 27]\
\
RFC 4444                       IS-IS MIB                      April 2006\
\
\
        DESCRIPTION\
            "If this object is non-zero, the overload bit is set at\
             this level when the isisSysAdminState variable goes to\
             state 'on' for this Intermediate System.  The overload bit\
             remains set for isisSysLevelSetOverloadUntil seconds.\
             When isisSysLevelSetOverloadUntil seconds have elapsed,\
             the overload flag remains set if the implementation has\
             run out of memory, or if it is set manually using the\
             isisSysLevelSetOverload object.\
\
             If isisSysLevelSetOverload is false, the system clears\
             the overload bit when isisSysLevelSetOverloadUntil seconds\
             have elapsed, if the system has not run out of memory."\
    ::= { isisSysLevelEntry 6 }\
\
    isisSysLevelMetricStyle OBJECT-TYPE\
        SYNTAX IsisMetricStyle\
        MAX-ACCESS read-write\
        STATUS current\
        DESCRIPTION\
            "Which style of metric do we generate in our LSPs\
             at this level?"\
        DEFVAL { narrow }\
    ::= { isisSysLevelEntry 7 }\
\
    isisSysLevelSPFConsiders OBJECT-TYPE\
        SYNTAX IsisMetricStyle\
        MAX-ACCESS read-write\
        STATUS current\
        DESCRIPTION\
            "Which style of metric do we consider in our\
             SPF computation at this level?"\
        DEFVAL { narrow }\
    ::= { isisSysLevelEntry 8 }\
\
    isisSysLevelTEEnabled OBJECT-TYPE\
        SYNTAX TruthValue\
        MAX-ACCESS read-write\
        STATUS current\
        DESCRIPTION\
            "Do we do Traffic Engineering at this level?"\
        DEFVAL { false }\
    ::= { isisSysLevelEntry 9 }\
\
-- Static to provide next CircIndex\
\
    isisNextCircIndex OBJECT-TYPE\
        SYNTAX IndexIntegerNextFree\
\
\
\
Parker                      Standards Track                    [Page 28]\
\
RFC 4444                       IS-IS MIB                      April 2006\
\
\
        MAX-ACCESS read-only\
        STATUS current\
        DESCRIPTION\
            "This object is used to assist a management\
             application in creating new rows in the\
             isisCircTable.  If it is possible to create\
             a new instance of isisCircEntry, then this\
             object will contain a non-zero value that\
             is not in use as the index of any row in the\
             isisCircTable.  The network manager reads the\
             value of this object and then (if the\
             value read is non-zero) attempts to create\
             the corresponding instance of isisCircEntry.\
             If the set request fails with the code\
             'inconsistentValue', then the process must be\
             repeated;  if the set request succeeds, then\
             the agent will change the value of this object\
             according to an implementation-specific\
             algorithm."\
    ::= { isisCirc  1 }\
\
-- The Circuit Table\
-- Each broadcast or point-to-point interface on the system\
-- corresponds to one entry in the Circuit table.  However, there\
-- may be multiple X.25 DA circuit entries in the Circuit table\
-- for a given X.25 interface.\
\
    isisCircTable OBJECT-TYPE\
        SYNTAX SEQUENCE OF IsisCircEntry\
        MAX-ACCESS not-accessible\
        STATUS current\
        DESCRIPTION\
            "The table of circuits used by this\
             Intermediate System."\
    ::= { isisCirc 2 }\
\
    isisCircEntry OBJECT-TYPE\
        SYNTAX IsisCircEntry\
        MAX-ACCESS not-accessible\
        STATUS current\
        DESCRIPTION\
            "An isisCircEntry exists for each circuit configured\
             for Integrated IS-IS on this system.\
\
             Dynamically created rows MUST survive an agent reboot."\
        INDEX { isisCircIndex }\
    ::= { isisCircTable 1 }\
\
\
\
\
Parker                      Standards Track                    [Page 29]\
\
RFC 4444                       IS-IS MIB                      April 2006\
\
\
    IsisCircEntry ::=\
        SEQUENCE {\
            isisCircIndex\
                IndexInteger,\
            isisCircIfIndex\
                InterfaceIndex,\
            isisCircAdminState\
                IsisAdminState,\
            isisCircExistState\
                RowStatus,\
            isisCircType\
                INTEGER,\
            isisCircExtDomain\
                TruthValue,\
            isisCircLevelType\
                IsisLevel,\
            isisCircPassiveCircuit\
                TruthValue,\
            isisCircMeshGroupEnabled\
                INTEGER,\
            isisCircMeshGroup\
                Unsigned32,\
            isisCircSmallHellos\
                TruthValue,\
            isisCircLastUpTime\
                TimeStamp,\
            isisCirc3WayEnabled\
                TruthValue,\
            isisCircExtendedCircID\
                Unsigned32\
        }\
\
    isisCircIndex OBJECT-TYPE\
        SYNTAX IndexInteger\
        MAX-ACCESS not-accessible\
        STATUS current\
        DESCRIPTION\
            "An index used to uniquely identify this circuit.\
             When creating a row in this table, the\
             isisNextCircIndex object should be retrieved,\
             and its value should be specified as the value\
             of this index using a SET operation.  A retrieved\
             value of zero(0) indicates that no rows can be\
             created at this time."\
    ::= { isisCircEntry 1 }\
\
    isisCircIfIndex OBJECT-TYPE\
        SYNTAX InterfaceIndex\
\
\
\
Parker                      Standards Track                    [Page 30]\
\
RFC 4444                       IS-IS MIB                      April 2006\
\
\
        MAX-ACCESS read-create\
        STATUS current\
        DESCRIPTION\
            "The value of ifIndex for the interface to which this\
             circuit corresponds.  This object cannot be modified\
             after creation."\
    ::= { isisCircEntry 2 }\
\
    isisCircAdminState OBJECT-TYPE\
        SYNTAX IsisAdminState\
        MAX-ACCESS read-create\
        STATUS current\
        DESCRIPTION\
            "The administrative state of the circuit."\
        DEFVAL { off }\
    ::= { isisCircEntry 3 }\
\
    isisCircExistState OBJECT-TYPE\
        SYNTAX RowStatus\
        MAX-ACCESS read-create\
        STATUS current\
        DESCRIPTION\
            "The existence state of this circuit.  Setting the state\
             to 'notInService' halts the generation and processing of\
             IS-IS protocol PDUs on this circuit.  Setting the state\
             to destroy will also erase any configuration associated\
             with the circuit.  Support for 'createAndWait' and\
             'notInService' is not required.\
\
             A row entry cannot be modified when the value of this\
             object is 'active'."\
    ::= { isisCircEntry 4 }\
\
    isisCircType OBJECT-TYPE\
        SYNTAX INTEGER\
            {\
                broadcast(1),\
                ptToPt(2),\
                staticIn(3),\
                staticOut(4),\
                dA(5)\
            }\
        MAX-ACCESS read-create\
        STATUS current\
        DESCRIPTION\
            "The type of the circuit.  This object follows the\
             ReplaceOnlyWhileDisabled behavior.  The type specified\
             must be compatible with the type of the interface defined\
\
\
\
Parker                      Standards Track                    [Page 31]\
\
RFC 4444                       IS-IS MIB                      April 2006\
\
\
             by the value of isisCircIfIndex."\
        REFERENCE "{ISIS.aoi type (33)}"\
    ::= { isisCircEntry 5 }\
\
    isisCircExtDomain OBJECT-TYPE\
        SYNTAX TruthValue\
        MAX-ACCESS read-create\
        STATUS current\
        DESCRIPTION\
            "If true, suppress normal transmission of and\
             interpretation of Intra-domain IS-IS PDUs on this\
             circuit."\
        REFERENCE "{ISIS.aoi externalDomain (46)}"\
        DEFVAL { false }\
    ::= { isisCircEntry 6 }\
\
    isisCircLevelType OBJECT-TYPE\
        SYNTAX IsisLevel\
        MAX-ACCESS read-create\
        STATUS current\
        DESCRIPTION\
            "Indicates which type of packets will be sent and\
             accepted on this circuit.  The values set will be\
             saved, but the values used will be modified by\
             the settings of isisSysLevelType.  Thus, if the\
             isisSysTpe is level2 and the isisCircLevelType\
             for a circuit is level1, the circuit will not send\
             or receive IS-IS packets.  This object follows the\
             ReplaceOnlyWhileDisabled behavior."\
        DEFVAL { level1and2 }\
    ::= { isisCircEntry 7 }\
\
    isisCircPassiveCircuit OBJECT-TYPE\
        SYNTAX TruthValue\
        MAX-ACCESS read-create\
        STATUS current\
        DESCRIPTION\
            "Should we include this interface in LSPs, even if\
             it is not running the IS-IS Protocol?"\
        DEFVAL { false }\
    ::= { isisCircEntry 8 }\
\
    isisCircMeshGroupEnabled OBJECT-TYPE\
        SYNTAX INTEGER\
            {\
                inactive(1),\
                blocked(2),\
                set(3)\
\
\
\
Parker                      Standards Track                    [Page 32]\
\
RFC 4444                       IS-IS MIB                      April 2006\
\
\
            }\
        MAX-ACCESS read-create\
        STATUS current\
        DESCRIPTION\
            "Is this port a member of a mesh group, or is it\
             blocked?  Circuits in the same mesh group act as a\
             virtual multiaccess network.  LSPs seen on one circuit\
             in a mesh group will not be flooded to another circuit\
             in the same mesh group."\
        REFERENCE "{ RFC 2973 }"\
        DEFVAL { inactive }\
    ::= { isisCircEntry 9 }\
\
    isisCircMeshGroup OBJECT-TYPE\
        SYNTAX Unsigned32\
        MAX-ACCESS read-create\
        STATUS current\
        DESCRIPTION\
            "Circuits in the same mesh group act as a virtual\
             multiaccess network.  LSPs seen on one circuit in\
             a mesh group will not be flooded to another circuit\
             in the same mesh group.  If isisCircMeshGroupEnabled\
             is inactive or blocked, this value is ignored."\
        REFERENCE "{ RFC 2973 }"\
    ::= { isisCircEntry 10 }\
\
    isisCircSmallHellos OBJECT-TYPE\
        SYNTAX TruthValue\
        MAX-ACCESS read-create\
        STATUS current\
        DESCRIPTION\
            "Can we send unpadded hellos on LAN circuits?  False\
             means the LAN Hellos must be padded.\
             Implementations should allow the administrator to read\
             this value.  An implementation need not be able to\
             support unpadded hellos to be conformant."\
         DEFVAL { false }\
    ::= { isisCircEntry 11 }\
\
    isisCircLastUpTime OBJECT-TYPE\
        SYNTAX TimeStamp\
        MAX-ACCESS read-only\
        STATUS current\
        DESCRIPTION\
            "How long the circuit has been enabled, measured in\
             hundredths of seconds since the last re-initialization\
             of the network management subsystem; 0 if the\
             circuit has never been 'on'."\
\
\
\
Parker                      Standards Track                    [Page 33]\
\
RFC 4444                       IS-IS MIB                      April 2006\
\
\
    ::= { isisCircEntry 12 }\
\
    isisCirc3WayEnabled OBJECT-TYPE\
        SYNTAX TruthValue\
        MAX-ACCESS read-create\
        STATUS current\
        DESCRIPTION\
            "Is this circuit enabled to run 3Way handshake?"\
        DEFVAL { true }\
    ::= { isisCircEntry 13 }\
\
    isisCircExtendedCircID OBJECT-TYPE\
        SYNTAX Unsigned32\
        MAX-ACCESS read-create\
        STATUS current\
        DESCRIPTION\
            "The value to be used as the extended circuit ID in\
             3Way handshake.  This value is only used if\
             isisCirc3WayEnabled is true, and it must be unique\
             across all circuits on this IS."\
    ::= { isisCircEntry 14 }\
\
-- The Circuit Level Table\
-- This table captures level-specific information about a circuit\
\
    isisCircLevelTable OBJECT-TYPE\
        SYNTAX SEQUENCE OF IsisCircLevelEntry\
        MAX-ACCESS not-accessible\
        STATUS current\
        DESCRIPTION\
            "Level specific information about circuits used by IS-IS."\
    ::= { isisCircLevelValues 1 }\
\
    isisCircLevelEntry OBJECT-TYPE\
        SYNTAX IsisCircLevelEntry\
        MAX-ACCESS not-accessible\
        STATUS current\
        DESCRIPTION\
            "An isisCircLevelEntry exists for each level on\
             each circuit configured for Integrated IS-IS on\
             this system.\
\
             Configured values MUST survive an agent reboot."\
        INDEX { isisCircIndex,\
                isisCircLevelIndex }\
    ::= { isisCircLevelTable 1 }\
\
    IsisCircLevelEntry ::=\
\
\
\
Parker                      Standards Track                    [Page 34]\
\
RFC 4444                       IS-IS MIB                      April 2006\
\
\
        SEQUENCE {\
            isisCircLevelIndex\
                IsisISLevel,\
            isisCircLevelMetric\
                IsisDefaultMetric,\
            isisCircLevelWideMetric\
                IsisWideMetric,\
            isisCircLevelISPriority\
                IsisISPriority,\
            isisCircLevelIDOctet\
                Unsigned32,\
            isisCircLevelID\
                IsisCircuitID,\
            isisCircLevelDesIS\
                IsisCircuitID,\
            isisCircLevelHelloMultiplier\
                Unsigned32,\
            isisCircLevelHelloTimer\
                Unsigned32,\
            isisCircLevelDRHelloTimer\
                Unsigned32,\
            isisCircLevelLSPThrottle\
                IsisUnsigned16TC,\
            isisCircLevelMinLSPRetransInt\
                Unsigned32,\
            isisCircLevelCSNPInterval\
                Unsigned32,\
            isisCircLevelPartSNPInterval\
                Unsigned32\
        }\
\
    isisCircLevelIndex OBJECT-TYPE\
        SYNTAX IsisISLevel\
        MAX-ACCESS not-accessible\
        STATUS current\
        DESCRIPTION\
            "The level that this entry describes."\
    ::= { isisCircLevelEntry 1 }\
\
    isisCircLevelMetric OBJECT-TYPE\
        SYNTAX IsisDefaultMetric\
        MAX-ACCESS read-write\
        STATUS current\
        DESCRIPTION\
            "The metric value of this circuit for this level."\
        REFERENCE "{ISIS.aoi l1DefaultMetric (35)}"\
        DEFVAL { 10 }\
    ::= { isisCircLevelEntry 2 }\
\
\
\
Parker                      Standards Track                    [Page 35]\
\
RFC 4444                       IS-IS MIB                      April 2006\
\
\
    isisCircLevelWideMetric OBJECT-TYPE\
        SYNTAX IsisWideMetric\
        MAX-ACCESS read-write\
        STATUS current\
        DESCRIPTION\
            "The wide metric value of this circuit for this level."\
        DEFVAL { 10 }\
    ::= { isisCircLevelEntry 3 }\
\
    isisCircLevelISPriority OBJECT-TYPE\
        SYNTAX IsisISPriority\
        MAX-ACCESS read-write\
        STATUS current\
        DESCRIPTION\
            "The priority for becoming the LAN-Designated\
             Intermediate System at this level."\
        REFERENCE "{ISIS.aoi l2IntermediateSystemPriority (73)}"\
        DEFVAL { 64 }\
    ::= { isisCircLevelEntry 4 }\
\
    isisCircLevelIDOctet OBJECT-TYPE\
        SYNTAX Unsigned32(0..255)\
        MAX-ACCESS read-only\
        STATUS current\
        DESCRIPTION\
            "A one-byte identifier for the circuit selected by the\
             Intermediate System.\
\
             On point-to-point circuits, the value is used as the Local\
             Circuit ID in point-to-point IIH PDUs transmitted on this\
             circuit.  In this case, values of isisCircLevelIDOctet do\
             not need to be unique.\
\
             For broadcast circuits, the value is used to generate the\
             LAN ID that will be used if this Intermediate System is\
             elected as the Designated IS on this circuit.  The value\
             is required to differ on LANs where the Intermediate System\
             is the Designated Intermediate System."\
    ::= { isisCircLevelEntry 5 }\
\
    isisCircLevelID OBJECT-TYPE\
        SYNTAX IsisCircuitID\
        MAX-ACCESS read-only\
        STATUS current\
        DESCRIPTION\
            "On a point-to-point circuit with a fully initialized\
             adjacency to a peer IS, the value of this object is\
             the circuit ID negotiated during adjacency initialization.\
\
\
\
Parker                      Standards Track                    [Page 36]\
\
RFC 4444                       IS-IS MIB                      April 2006\
\
\
             On a point to point circuit without such an adjacency,\
             the value is the concatenation of the local system ID\
             and the one-byte isisCircLevelIDOctet for this circuit,\
             i.e., the value that would be proposed for the circuit ID.\
             On other circuit types, the value returned is the zero-\
             length OCTET STRING."\
        REFERENCE "{ISIS.aoi ptPtCircuitID (51)}"\
    ::= { isisCircLevelEntry 6 }\
\
    isisCircLevelDesIS OBJECT-TYPE\
        SYNTAX IsisCircuitID\
        MAX-ACCESS read-only\
        STATUS current\
        DESCRIPTION\
            "The ID of the LAN-Designated Intermediate System\
             on this circuit at this level.  If, for any reason,\
             this system is not partaking in the relevant\
             Designated Intermediate System election process,\
             then the value returned is the zero-length OCTET STRING."\
        REFERENCE "{ISIS.aoi l2DesignatedIntermediateSystem (75)}"\
    ::= { isisCircLevelEntry 7 }\
\
    isisCircLevelHelloMultiplier OBJECT-TYPE\
        SYNTAX Unsigned32 (2..100)\
        MAX-ACCESS read-write\
        STATUS current\
        DESCRIPTION\
            "This value is multiplied by the corresponding HelloTimer,\
             and the result in seconds (rounded up) is used as the\
             holding time in transmitted hellos, to be used by\
             receivers of hello packets from this IS."\
        REFERENCE "{ISIS.aoi iSISHelloTimer (45)}"\
        DEFVAL { 10 }\
    ::= { isisCircLevelEntry 8 }\
\
    isisCircLevelHelloTimer OBJECT-TYPE\
        SYNTAX Unsigned32 (10..600000)\
        UNITS "milliseconds"\
        MAX-ACCESS read-write\
        STATUS current\
        DESCRIPTION\
            "Maximum period, in milliseconds, between IIH PDUs\
             on multiaccess networks at this level for LANs.\
             The value at L1 is used as the period between\
             Hellos on L1L2 point-to-point circuits.  Setting\
             this value at level 2 on an L1L2 point-to-point\
             circuit will result in an error of InconsistentValue.\
\
\
\
\
Parker                      Standards Track                    [Page 37]\
\
RFC 4444                       IS-IS MIB                      April 2006\
\
\
             This object follows the ResettingTimer behavior."\
        REFERENCE "{ISIS.aoi iSISHelloTimer (45)}"\
        DEFVAL { 3000 }\
    ::= { isisCircLevelEntry 9 }\
\
    isisCircLevelDRHelloTimer OBJECT-TYPE\
        SYNTAX Unsigned32 (10..120000)\
        UNITS "milliseconds"\
        MAX-ACCESS read-write\
        STATUS current\
        DESCRIPTION\
            "Period, in milliseconds, between Hello PDUs on\
             multiaccess networks when this IS is the Designated\
             Intermediate System.  This object follows the\
             ResettingTimer behavior."\
        REFERENCE "{ISIS.aoi iSISHelloTimer (45)}"\
        DEFVAL { 1000 }\
    ::= { isisCircLevelEntry 10 }\
\
    isisCircLevelLSPThrottle OBJECT-TYPE\
        SYNTAX IsisUnsigned16TC (1..65535)\
        UNITS "milliseconds"\
        MAX-ACCESS read-write\
        STATUS current\
        DESCRIPTION\
            "Minimal interval of time, in milliseconds, between\
             transmissions of LSPs on an interface at this level."\
        REFERENCE\
            "{ISIS.aoi minimumBroadcastLSPTransmissionInterval (5)}"\
        DEFVAL { 30 }\
    ::= { isisCircLevelEntry 11 }\
\
    isisCircLevelMinLSPRetransInt OBJECT-TYPE\
        SYNTAX Unsigned32 (1..300)\
        UNITS "seconds"\
        MAX-ACCESS read-write\
        STATUS current\
        DESCRIPTION\
            "Minimum interval, in seconds, between re-transmission of\
             an LSP at this level.  This object follows the\
             ResettingTimer behavior.\
\
             Note that isisCircLevelLSPThrottle controls\
             how fast we send back-to-back LSPs.  This variable\
             controls how fast we re-send the same LSP."\
        REFERENCE "{ISIS.aoi minimumLSPTransmissionInterval (5)}"\
        DEFVAL { 5 }\
    ::= { isisCircLevelEntry 12 }\
\
\
\
Parker                      Standards Track                    [Page 38]\
\
RFC 4444                       IS-IS MIB                      April 2006\
\
\
    isisCircLevelCSNPInterval OBJECT-TYPE\
        SYNTAX Unsigned32 (1..600)\
        UNITS "seconds"\
        MAX-ACCESS read-write\
        STATUS current\
        DESCRIPTION\
            "Interval of time, in seconds, between periodic\
             transmission of a complete set of CSNPs on\
             multiaccess networks if this router is the\
             designated router at this level.\
             This object follows the ResettingTimer behavior."\
        REFERENCE "{ISIS.aoi completeSNPInterval (8)}"\
        DEFVAL { 10 }\
    ::= { isisCircLevelEntry 13 }\
\
    isisCircLevelPartSNPInterval OBJECT-TYPE\
        SYNTAX Unsigned32 (1..120)\
        UNITS "seconds"\
        MAX-ACCESS read-write\
        STATUS current\
        DESCRIPTION\
            "Minimum interval, in seconds, between sending Partial\
             Sequence Number PDUs at this level.  This object\
             follows the ResettingTimer behavior."\
        REFERENCE "{ISIS.aoi partialSNPInterval (14)}"\
        DEFVAL { 2 }\
    ::= { isisCircLevelEntry 14 }\
\
-- isisSystemCounterTable keeps track of system-wide events.\
\
    isisSystemCounterTable OBJECT-TYPE\
        SYNTAX SEQUENCE OF IsisSystemCounterEntry\
        MAX-ACCESS not-accessible\
        STATUS current\
        DESCRIPTION\
            "System-wide counters for this Intermediate System."\
    ::= { isisCounters 1 }\
\
    isisSystemCounterEntry OBJECT-TYPE\
        SYNTAX IsisSystemCounterEntry\
        MAX-ACCESS not-accessible\
        STATUS current\
        DESCRIPTION\
            "System-wide IS-IS counters."\
        INDEX { isisSysStatLevel }\
    ::= { isisSystemCounterTable 1 }\
\
    IsisSystemCounterEntry ::=\
\
\
\
Parker                      Standards Track                    [Page 39]\
\
RFC 4444                       IS-IS MIB                      April 2006\
\
\
        SEQUENCE {\
            isisSysStatLevel\
                IsisISLevel,\
            isisSysStatCorrLSPs\
                Counter32,\
            isisSysStatAuthTypeFails\
                Counter32,\
            isisSysStatAuthFails\
                Counter32,\
            isisSysStatLSPDbaseOloads\
                Counter32,\
            isisSysStatManAddrDropFromAreas\
                Counter32,\
            isisSysStatAttmptToExMaxSeqNums\
                Counter32,\
            isisSysStatSeqNumSkips\
                Counter32,\
            isisSysStatOwnLSPPurges\
                Counter32,\
            isisSysStatIDFieldLenMismatches\
                Counter32,\
            isisSysStatPartChanges\
                Counter32,\
            isisSysStatSPFRuns\
                Counter32,\
            isisSysStatLSPErrors\
                Counter32\
        }\
\
    isisSysStatLevel OBJECT-TYPE\
        SYNTAX IsisISLevel\
        MAX-ACCESS not-accessible\
        STATUS current\
        DESCRIPTION\
            "The level that this entry describes."\
    ::= { isisSystemCounterEntry 1 }\
\
    isisSysStatCorrLSPs OBJECT-TYPE\
        SYNTAX Counter32\
        UNITS "Number of corrupted in-memory frames"\
        MAX-ACCESS read-only\
        STATUS current\
        DESCRIPTION\
            "Number of corrupted in-memory LSPs detected.\
\
             LSPs received from the wire with a bad checksum\
             are silently dropped and are not counted.\
\
\
\
\
Parker                      Standards Track                    [Page 40]\
\
RFC 4444                       IS-IS MIB                      April 2006\
\
\
             LSPs received from the wire with parse errors\
             are counted by isisSysStatLSPErrors."\
        REFERENCE "{ISIS.aoi corruptedLSPsDetected (19)}"\
    ::= { isisSystemCounterEntry 2 }\
\
    isisSysStatAuthTypeFails OBJECT-TYPE\
        SYNTAX Counter32\
        UNITS "Number of frames with authentication type mismatches"\
        MAX-ACCESS read-only\
        STATUS current\
        DESCRIPTION\
            "The number of authentication type mismatches recognized\
             by this Intermediate System."\
    ::= { isisSystemCounterEntry 3 }\
\
    isisSysStatAuthFails OBJECT-TYPE\
        SYNTAX Counter32\
        UNITS "Number of frames with authentication key failures"\
        MAX-ACCESS read-only\
        STATUS current\
        DESCRIPTION\
            "The number of authentication key failures recognized\
             by this Intermediate System."\
    ::= { isisSystemCounterEntry 4 }\
\
    isisSysStatLSPDbaseOloads OBJECT-TYPE\
        SYNTAX Counter32\
        MAX-ACCESS read-only\
        STATUS current\
        DESCRIPTION\
            "Number of times the LSP database has become\
             overloaded."\
        REFERENCE "{ISIS.aoi lSPL1DatabaseOverloads (20)}"\
    ::= { isisSystemCounterEntry 5 }\
\
    isisSysStatManAddrDropFromAreas OBJECT-TYPE\
        SYNTAX Counter32\
        MAX-ACCESS read-only\
        STATUS current\
        DESCRIPTION\
            "Number of times a manual address has been dropped from\
             the area."\
        REFERENCE "{ISIS.aoi manualAddressesDroppedFromArea (21)}"\
    ::= { isisSystemCounterEntry 6 }\
\
    isisSysStatAttmptToExMaxSeqNums OBJECT-TYPE\
        SYNTAX Counter32\
        MAX-ACCESS read-only\
\
\
\
Parker                      Standards Track                    [Page 41]\
\
RFC 4444                       IS-IS MIB                      April 2006\
\
\
        STATUS current\
        DESCRIPTION\
            "Number of times the IS has attempted to exceed the\
             maximum sequence number."\
        REFERENCE\
            "{ISIS.aoi attemptsToExceedmaximumSequenceNumber (22)}"\
    ::= { isisSystemCounterEntry 7 }\
\
    isisSysStatSeqNumSkips OBJECT-TYPE\
        SYNTAX Counter32\
        MAX-ACCESS read-only\
        STATUS current\
        DESCRIPTION\
            "Number of times a sequence number skip has occurred."\
        REFERENCE "{ISIS.aoi sequenceNumberSkips (23)}"\
    ::= { isisSystemCounterEntry 8 }\
\
    isisSysStatOwnLSPPurges OBJECT-TYPE\
        SYNTAX Counter32\
        MAX-ACCESS read-only\
        STATUS current\
        DESCRIPTION\
            "Number of times a zero-aged copy of the system's own LSP\
             is received from some other node."\
        REFERENCE "{ISIS.aoi ownLSPPurges (24)}"\
    ::= { isisSystemCounterEntry 9 }\
\
    isisSysStatIDFieldLenMismatches OBJECT-TYPE\
        SYNTAX Counter32\
        UNITS "Number of frames with ID length mismatches"\
        MAX-ACCESS read-only\
        STATUS current\
        DESCRIPTION\
            "Number of times a PDU is received with a different value\
             for ID field length from that of the receiving system."\
        REFERENCE "{ISIS.aoi iDFieldLengthMismatches (25)}"\
    ::= { isisSystemCounterEntry 10 }\
\
    isisSysStatPartChanges OBJECT-TYPE\
        SYNTAX Counter32\
        MAX-ACCESS read-only\
        STATUS current\
        DESCRIPTION\
            "Partition changes."\
    ::= { isisSystemCounterEntry 11 }\
\
    isisSysStatSPFRuns OBJECT-TYPE\
        SYNTAX Counter32\
\
\
\
Parker                      Standards Track                    [Page 42]\
\
RFC 4444                       IS-IS MIB                      April 2006\
\
\
        MAX-ACCESS read-only\
        STATUS current\
        DESCRIPTION\
            "Number of times we ran SPF at this level."\
    ::= { isisSystemCounterEntry 12 }\
\
    isisSysStatLSPErrors OBJECT-TYPE\
        SYNTAX Counter32\
        UNITS "Number of frames with errors that we have received"\
        MAX-ACCESS read-only\
        STATUS current\
        DESCRIPTION\
            "Number of LSPs with errors we have received."\
    ::= { isisSystemCounterEntry 13 }\
\
-- isisCircuitCounterTable keeps track of events\
-- specific to a circuit and a level\
\
    isisCircuitCounterTable OBJECT-TYPE\
        SYNTAX SEQUENCE OF IsisCircuitCounterEntry\
        MAX-ACCESS not-accessible\
        STATUS current\
        DESCRIPTION\
            "Circuit specific counters for this\
             Intermediate System."\
    ::= { isisCounters 2 }\
\
    isisCircuitCounterEntry OBJECT-TYPE\
        SYNTAX IsisCircuitCounterEntry\
        MAX-ACCESS not-accessible\
        STATUS current\
        DESCRIPTION\
            "An isisCircuitCounterEntry exists for each circuit\
             used by Integrated IS-IS on this system."\
        INDEX { isisCircIndex,\
                isisCircuitType }\
    ::= { isisCircuitCounterTable 1 }\
\
    IsisCircuitCounterEntry ::= SEQUENCE {\
          isisCircuitType\
              INTEGER,\
          isisCircAdjChanges\
              Counter32,\
          isisCircNumAdj\
              Unsigned32,\
          isisCircInitFails\
              Counter32,\
          isisCircRejAdjs\
\
\
\
Parker                      Standards Track                    [Page 43]\
\
RFC 4444                       IS-IS MIB                      April 2006\
\
\
              Counter32,\
          isisCircIDFieldLenMismatches\
              Counter32,\
          isisCircMaxAreaAddrMismatches\
              Counter32,\
          isisCircAuthTypeFails\
              Counter32,\
          isisCircAuthFails\
              Counter32,\
          isisCircLANDesISChanges\
              Counter32\
       }\
\
    isisCircuitType OBJECT-TYPE\
        SYNTAX INTEGER\
            {\
                lanlevel1(1),\
                lanlevel2(2),\
                p2pcircuit(3)\
            }\
        MAX-ACCESS not-accessible\
        STATUS current\
        DESCRIPTION\
            "What type of circuit saw these counts?\
\
             The point-to-point Hello PDU includes\
             both L1 and L2, and ISs form a single\
             adjacency on point-to-point links.\
             Thus, we combine counts on\
             point-to-point links into one group."\
    ::= { isisCircuitCounterEntry 1 }\
\
    isisCircAdjChanges OBJECT-TYPE\
        SYNTAX Counter32\
        MAX-ACCESS read-only\
        STATUS current\
        DESCRIPTION\
            "The number of times an adjacency state change has\
             occurred on this circuit."\
        REFERENCE "{ISIS.aoi changesInAdjacencyState (40)}"\
    ::= { isisCircuitCounterEntry 2 }\
\
    isisCircNumAdj OBJECT-TYPE\
        SYNTAX Unsigned32\
        MAX-ACCESS read-only\
        STATUS current\
        DESCRIPTION\
            "The number of adjacencies on this circuit."\
\
\
\
Parker                      Standards Track                    [Page 44]\
\
RFC 4444                       IS-IS MIB                      April 2006\
\
\
        REFERENCE "{ISIS.aoi changesInAdjacencyState (40)}"\
    ::= { isisCircuitCounterEntry 3 }\
\
    isisCircInitFails OBJECT-TYPE\
        SYNTAX Counter32\
        MAX-ACCESS read-only\
        STATUS current\
        DESCRIPTION\
            "The number of times initialization of this circuit has\
             failed.  This counts events such as PPP NCP failures.\
             Failures to form an adjacency are counted by\
             isisCircRejAdjs."\
    ::= { isisCircuitCounterEntry 4 }\
\
    isisCircRejAdjs OBJECT-TYPE\
        SYNTAX Counter32\
        MAX-ACCESS read-only\
        STATUS current\
        DESCRIPTION\
            "The number of times an adjacency has been rejected on\
             this circuit."\
        REFERENCE "{ISIS.aoi rejectedAdjacencies (42)}"\
    ::= { isisCircuitCounterEntry 5 }\
\
    isisCircIDFieldLenMismatches OBJECT-TYPE\
        SYNTAX Counter32\
        UNITS "Number of frames with ID field length mismatch"\
        MAX-ACCESS read-only\
        STATUS current\
        DESCRIPTION\
            "The number of times an IS-IS control PDU with an ID\
             field length different from that for this system has been\
             received."\
        REFERENCE "{ISIS.aoi iDFieldLengthMismatches (25)}"\
    ::= { isisCircuitCounterEntry 6 }\
\
    isisCircMaxAreaAddrMismatches OBJECT-TYPE\
        SYNTAX Counter32\
        MAX-ACCESS read-only\
        STATUS current\
        DESCRIPTION\
            "The number of times an IS-IS control PDU with a\
             max area address field different from that for this\
             system has been received."\
        REFERENCE "{ISIS.aoi iDFieldLengthMismatches (25)}"\
    ::= { isisCircuitCounterEntry 7 }\
\
    isisCircAuthTypeFails OBJECT-TYPE\
\
\
\
Parker                      Standards Track                    [Page 45]\
\
RFC 4444                       IS-IS MIB                      April 2006\
\
\
        SYNTAX Counter32\
        MAX-ACCESS read-only\
        STATUS current\
        DESCRIPTION\
            "The number of times an IS-IS control PDU with\
             an auth type field different from that for this\
             system has been received."\
    ::= { isisCircuitCounterEntry 8 }\
\
    isisCircAuthFails OBJECT-TYPE\
        SYNTAX Counter32\
        MAX-ACCESS read-only\
        STATUS current\
        DESCRIPTION\
            "The number of times an IS-IS control PDU with\
             the correct auth type has failed to pass authentication\
             validation."\
    ::= { isisCircuitCounterEntry 9 }\
\
    isisCircLANDesISChanges OBJECT-TYPE\
        SYNTAX Counter32\
        MAX-ACCESS read-only\
        STATUS current\
        DESCRIPTION\
            "The number of times the Designated IS has changed\
             on this circuit at this level.  If the circuit is\
             point to point, this count is zero."\
    ::= { isisCircuitCounterEntry 10 }\
\
-- isisPacketCounterTable keeps track of the number of IS-IS\
-- control packets sent and received at each level\
\
    isisPacketCounterTable OBJECT-TYPE\
        SYNTAX SEQUENCE OF IsisPacketCounterEntry\
        MAX-ACCESS not-accessible\
        STATUS current\
        DESCRIPTION\
            "Information about IS-IS protocol traffic at one level,\
             on one circuit, in one direction."\
    ::= { isisCounters 3 }\
\
    isisPacketCounterEntry OBJECT-TYPE\
        SYNTAX IsisPacketCounterEntry\
        MAX-ACCESS not-accessible\
        STATUS current\
        DESCRIPTION\
            "Information about IS-IS protocol traffic at one level,\
             on one circuit, in one direction."\
\
\
\
Parker                      Standards Track                    [Page 46]\
\
RFC 4444                       IS-IS MIB                      April 2006\
\
\
        INDEX { isisCircIndex,\
                isisPacketCountLevel,\
                isisPacketCountDirection }\
    ::= { isisPacketCounterTable 1 }\
\
    IsisPacketCounterEntry ::=\
        SEQUENCE {\
            isisPacketCountLevel\
                IsisISLevel,\
            isisPacketCountDirection\
                INTEGER,\
            isisPacketCountIIHello\
                Counter32,\
            isisPacketCountISHello\
                Counter32,\
            isisPacketCountESHello\
                Counter32,\
            isisPacketCountLSP\
                Counter32,\
            isisPacketCountCSNP\
                Counter32,\
            isisPacketCountPSNP\
                Counter32,\
            isisPacketCountUnknown\
                Counter32\
    }\
\
    isisPacketCountLevel OBJECT-TYPE\
        SYNTAX IsisISLevel\
        MAX-ACCESS not-accessible\
        STATUS current\
        DESCRIPTION\
            "The level at which these PDU counts have been collected."\
    ::= { isisPacketCounterEntry 1 }\
\
    isisPacketCountDirection OBJECT-TYPE\
        SYNTAX INTEGER\
            {\
                sending(1),\
                receiving(2)\
            }\
        MAX-ACCESS not-accessible\
        STATUS current\
        DESCRIPTION\
            "Were we sending or receiving these PDUs?"\
    ::= { isisPacketCounterEntry 2 }\
\
    isisPacketCountIIHello OBJECT-TYPE\
\
\
\
Parker                      Standards Track                    [Page 47]\
\
RFC 4444                       IS-IS MIB                      April 2006\
\
\
        SYNTAX Counter32\
        UNITS "Number of IS-IS Hellos frames seen in this direction\
              at this level"\
        MAX-ACCESS read-only\
        STATUS current\
        DESCRIPTION\
            "The number of IS-IS Hello PDUs seen in this\
             direction at this level.\
\
             Point-to-Point IIH PDUs are counted at\
             the lowest enabled level: at L1 on L1 or L1L2 circuits,\
             and at L2 otherwise."\
        REFERENCE "{ISIS.aoi iSISControlPDUsSent (43)}"\
    ::= { isisPacketCounterEntry 3 }\
\
    isisPacketCountISHello OBJECT-TYPE\
        SYNTAX Counter32\
        UNITS "Number of ES-IS frames seen in this direction at\
             this level."\
        MAX-ACCESS read-only\
        STATUS current\
        DESCRIPTION\
            "The number of ES-IS Hello PDUs seen in this\
             direction.  ISH PDUs are counted at the\
             lowest enabled level: at L1 on L1 or L1L2\
             circuits, and at L2 otherwise."\
    ::= { isisPacketCounterEntry 4 }\
\
    isisPacketCountESHello OBJECT-TYPE\
        SYNTAX Counter32\
        UNITS "Number of ES Hello frames seen in this direction at\
             this level"\
        MAX-ACCESS read-only\
        STATUS current\
        DESCRIPTION\
            "The number of ES Hello PDUs seen in this\
             direction.  ESH PDUs are counted at the\
             lowest enabled level: at L1 on L1 or L1L2\
             circuits, and at L2 otherwise."\
    ::= { isisPacketCounterEntry 5 }\
\
    isisPacketCountLSP OBJECT-TYPE\
        SYNTAX Counter32\
        UNITS "Number of IS-IS LSP frames seen in this direction at\
             this level"\
        MAX-ACCESS read-only\
        STATUS current\
        DESCRIPTION\
\
\
\
Parker                      Standards Track                    [Page 48]\
\
RFC 4444                       IS-IS MIB                      April 2006\
\
\
            "The number of IS-IS LSPs seen in this\
             direction at this level."\
        REFERENCE "{ISIS.aoi iSISControlPDUsSent (43)}"\
    ::= { isisPacketCounterEntry 6 }\
\
    isisPacketCountCSNP OBJECT-TYPE\
        SYNTAX Counter32\
        UNITS "Number of IS-IS CSNP frames seen in this direction at\
             this level"\
        MAX-ACCESS read-only\
        STATUS current\
        DESCRIPTION\
            "The number of IS-IS CSNPs seen in this\
             direction at this level."\
        REFERENCE "{ISIS.aoi iSISControlPDUsSent (43)}"\
    ::= { isisPacketCounterEntry 7 }\
\
    isisPacketCountPSNP OBJECT-TYPE\
        SYNTAX Counter32\
        UNITS "Number of IS-IS PSNP frames seen in this direction at\
             this level"\
        MAX-ACCESS read-only\
        STATUS current\
        DESCRIPTION\
            "The number of IS-IS PSNPs seen in this\
             direction at this level."\
        REFERENCE "{ISIS.aoi iSISControlPDUsSent (43)}"\
    ::= { isisPacketCounterEntry 8 }\
\
    isisPacketCountUnknown OBJECT-TYPE\
        SYNTAX Counter32\
        UNITS "Number of unknown IS-IS frames seen at this level"\
        MAX-ACCESS read-only\
        STATUS current\
        DESCRIPTION\
            "The number of unknown IS-IS PDUs seen\
             at this level."\
        REFERENCE "{ISIS.aoi iSISControlPDUsSent (43)}"\
    ::= { isisPacketCounterEntry 9 }\
\
-- The IS Adjacency Table\
--\
-- Each adjacency to an IS corresponds to one entry in this\
-- table.\
\
    isisISAdjTable OBJECT-TYPE\
        SYNTAX SEQUENCE OF IsisISAdjEntry\
        MAX-ACCESS not-accessible\
\
\
\
Parker                      Standards Track                    [Page 49]\
\
RFC 4444                       IS-IS MIB                      April 2006\
\
\
        STATUS current\
        DESCRIPTION\
            "The table of adjacencies to Intermediate Systems."\
    ::= { isisISAdj 1 }\
\
    isisISAdjEntry OBJECT-TYPE\
        SYNTAX IsisISAdjEntry\
        MAX-ACCESS not-accessible\
        STATUS current\
        DESCRIPTION\
            "Each entry corresponds to one adjacency to an\
             Intermediate System on this system.\
\
             Dynamically learned rows do not survive an agent reboot."\
        INDEX { isisCircIndex,\
                isisISAdjIndex }\
    ::= { isisISAdjTable 1 }\
\
    IsisISAdjEntry ::=\
        SEQUENCE {\
            isisISAdjIndex\
                Unsigned32,\
            isisISAdjState\
                INTEGER,\
            isisISAdj3WayState\
                INTEGER,\
            isisISAdjNeighSNPAAddress\
                IsisOSINSAddress,\
            isisISAdjNeighSysType\
                INTEGER,\
            isisISAdjNeighSysID\
                IsisSystemID,\
            isisISAdjNbrExtendedCircID\
                Unsigned32,\
            isisISAdjUsage\
                IsisLevel,\
            isisISAdjHoldTimer\
                IsisUnsigned16TC,\
            isisISAdjNeighPriority\
                IsisISPriority,\
            isisISAdjLastUpTime\
                TimeStamp\
      }\
\
    isisISAdjIndex OBJECT-TYPE\
        SYNTAX Unsigned32(1..4294967295)\
        MAX-ACCESS not-accessible\
        STATUS current\
\
\
\
Parker                      Standards Track                    [Page 50]\
\
RFC 4444                       IS-IS MIB                      April 2006\
\
\
        DESCRIPTION\
            "A unique value identifying the IS adjacency from all\
             other such adjacencies on this circuit.  This value is\
             automatically assigned by the system when the adjacency\
             is created."\
    ::= { isisISAdjEntry 1 }\
\
    isisISAdjState OBJECT-TYPE\
        SYNTAX INTEGER\
            {\
                 down (1),\
                 initializing (2),\
                 up (3),\
                 failed(4)\
            }\
        MAX-ACCESS read-only\
        STATUS current\
        DESCRIPTION\
            "The state of the adjacency."\
        REFERENCE "{ISIS.aoi adjacencyState (78)}"\
    ::= { isisISAdjEntry 2 }\
\
    isisISAdj3WayState OBJECT-TYPE\
        SYNTAX INTEGER\
            {\
                 up (0),\
                 initializing (1),\
                 down (2),\
                 failed (3)\
            }\
        MAX-ACCESS read-only\
        STATUS current\
        DESCRIPTION\
            "The 3Way state of the adjacency.  These are picked\
             to match the historical on-the-wire representation\
             of the 3Way state and are not intended to match\
             isisISAdjState."\
        REFERENCE "{ RFC 3373 }"\
    ::= { isisISAdjEntry 3 }\
\
    isisISAdjNeighSNPAAddress OBJECT-TYPE\
        SYNTAX IsisOSINSAddress\
        MAX-ACCESS read-only\
        STATUS current\
        DESCRIPTION\
            "The SNPA address of the neighboring system."\
        REFERENCE "{ISIS.aoi neighbourSNPAAddress (79)}"\
    ::= { isisISAdjEntry 4 }\
\
\
\
Parker                      Standards Track                    [Page 51]\
\
RFC 4444                       IS-IS MIB                      April 2006\
\
\
    isisISAdjNeighSysType OBJECT-TYPE\
        SYNTAX INTEGER\
            {\
                l1IntermediateSystem(1),\
                l2IntermediateSystem(2),\
                l1L2IntermediateSystem(3),\
                unknown(4)\
            }\
        MAX-ACCESS read-only\
        STATUS current\
        DESCRIPTION\
            "The type of the neighboring system."\
        REFERENCE "{ISIS.aoi neighbourSystemType (80)}"\
    ::= { isisISAdjEntry 5 }\
\
    isisISAdjNeighSysID OBJECT-TYPE\
        SYNTAX IsisSystemID\
        MAX-ACCESS read-only\
        STATUS current\
        DESCRIPTION\
            "The system ID of the neighboring Intermediate\
             System."\
        REFERENCE "{ISIS.aoi neighbourSystemIds (83)}"\
    ::= { isisISAdjEntry 6 }\
\
    isisISAdjNbrExtendedCircID OBJECT-TYPE\
        SYNTAX Unsigned32\
        MAX-ACCESS read-only\
        STATUS current\
        DESCRIPTION\
            "The 4-byte Extended Circuit ID learned from the\
             Neighbor during 3-way handshake, or 0."\
    ::= { isisISAdjEntry 7 }\
\
    isisISAdjUsage OBJECT-TYPE\
        SYNTAX IsisLevel\
        MAX-ACCESS read-only\
        STATUS current\
        DESCRIPTION\
            "How is the adjacency used?  On a point-to-point link,\
             this might be level1and2, but on a LAN, the usage will\
             be level1 on the adjacency between peers at L1,\
             and level2 for the adjacency between peers at L2."\
        REFERENCE "{ISIS.aoi adjacencyUsage (82)}"\
    ::= { isisISAdjEntry 8 }\
\
    isisISAdjHoldTimer OBJECT-TYPE\
        SYNTAX IsisUnsigned16TC (1..65535)\
\
\
\
Parker                      Standards Track                    [Page 52]\
\
RFC 4444                       IS-IS MIB                      April 2006\
\
\
        UNITS "seconds"\
        MAX-ACCESS read-only\
        STATUS current\
        DESCRIPTION\
            "The holding time, in seconds, for this adjacency.\
             This value is based on received IIH PDUs and\
             the elapsed time since receipt."\
        REFERENCE "{ISIS.aoi holdingTimer (85)}"\
    ::= { isisISAdjEntry 9 }\
\
    isisISAdjNeighPriority OBJECT-TYPE\
        SYNTAX IsisISPriority\
        MAX-ACCESS read-only\
        STATUS current\
        DESCRIPTION\
            "Priority of the neighboring Intermediate System for\
             becoming the Designated Intermediate System."\
        REFERENCE "{ISIS.aoi lANPriority (86)}"\
    ::= { isisISAdjEntry 10 }\
\
    isisISAdjLastUpTime OBJECT-TYPE\
        SYNTAX TimeStamp\
        MAX-ACCESS read-only\
        STATUS current\
        DESCRIPTION\
            "When the adjacency most recently entered the state 'up',\
             measured in hundredths of a second since the last\
             re-initialization of the network management subsystem.\
             Holds 0 if the adjacency has never been in state 'up'."\
    ::= { isisISAdjEntry 11 }\
\
-- The IS Adjacency Area Address Table\
\
-- The IS Adjacency Area Address Table contains the set of\
-- Area Addresses of neighboring\
-- Intermediate Systems as reported in IIH PDUs.\
\
    isisISAdjAreaAddrTable OBJECT-TYPE\
        SYNTAX SEQUENCE OF IsisISAdjAreaAddrEntry\
        MAX-ACCESS not-accessible\
        STATUS current\
        DESCRIPTION\
            "This table contains the set of Area Addresses of\
             neighboring Intermediate Systems as reported in received\
             IIH PDUs."\
        REFERENCE "{ISIS.aoi areaAddressesOfNeighbour (84)}"\
    ::= { isisISAdj 2 }\
\
\
\
\
Parker                      Standards Track                    [Page 53]\
\
RFC 4444                       IS-IS MIB                      April 2006\
\
\
    isisISAdjAreaAddrEntry OBJECT-TYPE\
        SYNTAX IsisISAdjAreaAddrEntry\
        MAX-ACCESS not-accessible\
        STATUS current\
        DESCRIPTION\
            "Each entry contains one Area Address reported by a\
             neighboring Intermediate System in its IIH PDUs.\
\
             Dynamically learned rows do not survive an agent reboot."\
        INDEX { isisCircIndex,\
                isisISAdjIndex,\
                isisISAdjAreaAddrIndex }\
    ::= { isisISAdjAreaAddrTable 1 }\
\
    IsisISAdjAreaAddrEntry ::=\
        SEQUENCE {\
            isisISAdjAreaAddrIndex\
                Unsigned32,\
            isisISAdjAreaAddress\
                IsisOSINSAddress\
            }\
\
    isisISAdjAreaAddrIndex OBJECT-TYPE\
        SYNTAX Unsigned32(1..4294967295)\
        MAX-ACCESS not-accessible\
        STATUS current\
        DESCRIPTION\
            "An index for the areas associated with one neighbor.\
             This provides a simple way to walk the table."\
    ::= { isisISAdjAreaAddrEntry 1 }\
\
    isisISAdjAreaAddress OBJECT-TYPE\
        SYNTAX IsisOSINSAddress\
        MAX-ACCESS read-only\
        STATUS current\
        DESCRIPTION\
            "One Area Address as reported in IIH PDUs received from\
             the neighbor."\
    ::= { isisISAdjAreaAddrEntry 2 }\
\
-- The IS Adjacency IP Address Table\
\
-- The IS Adjacency IP Address Table contains the\
-- set of IP Addresses of neighboring Intermediate Systems\
-- as reported in received IIH PDUs.\
\
    isisISAdjIPAddrTable OBJECT-TYPE\
        SYNTAX SEQUENCE OF IsisISAdjIPAddrEntry\
\
\
\
Parker                      Standards Track                    [Page 54]\
\
RFC 4444                       IS-IS MIB                      April 2006\
\
\
        MAX-ACCESS not-accessible\
        STATUS current\
        DESCRIPTION\
            "This table contains the set of IP Addresses of\
             neighboring Intermediate Systems as reported in received\
             IIH PDUs."\
    ::= { isisISAdj 3 }\
\
    isisISAdjIPAddrEntry OBJECT-TYPE\
        SYNTAX IsisISAdjIPAddrEntry\
        MAX-ACCESS not-accessible\
        STATUS current\
        DESCRIPTION\
            "Each entry contains one IP Address reported by a\
             neighboring Intermediate System in its IIH PDUs.\
\
             Dynamically learned rows do not survive an agent reboot."\
        INDEX { isisCircIndex,\
                isisISAdjIndex,\
                isisISAdjIPAddrIndex\
                }\
    ::= { isisISAdjIPAddrTable 1 }\
\
    IsisISAdjIPAddrEntry ::=\
        SEQUENCE {\
            isisISAdjIPAddrIndex\
                Unsigned32,\
            isisISAdjIPAddrType\
                 InetAddressType,\
            isisISAdjIPAddrAddress\
                InetAddress\
        }\
\
    isisISAdjIPAddrIndex OBJECT-TYPE\
        SYNTAX Unsigned32(1..4294967295)\
        MAX-ACCESS not-accessible\
        STATUS current\
        DESCRIPTION\
            "An index to this table that identifies the IP addresses\
             to which this entry belongs."\
    ::= { isisISAdjIPAddrEntry 1 }\
\
    isisISAdjIPAddrType OBJECT-TYPE\
        SYNTAX InetAddressType\
        MAX-ACCESS read-only\
        STATUS current\
        DESCRIPTION\
            "The type of one IP Address as reported in IIH PDUs\
\
\
\
Parker                      Standards Track                    [Page 55]\
\
RFC 4444                       IS-IS MIB                      April 2006\
\
\
             received from the neighbor."\
    ::= { isisISAdjIPAddrEntry 2 }\
\
    isisISAdjIPAddrAddress OBJECT-TYPE\
        SYNTAX InetAddress\
        MAX-ACCESS read-only\
        STATUS current\
        DESCRIPTION\
            "One IP Address as reported in IIH PDUs received from the\
             neighbor.\
\
             The type of this address is determined by the value of\
             the isisISAdjIPAddrType object."\
    ::= { isisISAdjIPAddrEntry 3 }\
\
-- The IS Adjacency Protocol Supported Table\
--\
-- The IS Adjacency Protocol Supported Table contains the set of\
-- protocols supported by neighboring\
-- Intermediate Systems as reported in received IIH PDUs.\
\
    isisISAdjProtSuppTable OBJECT-TYPE\
        SYNTAX SEQUENCE OF IsisISAdjProtSuppEntry\
        MAX-ACCESS not-accessible\
        STATUS current\
        DESCRIPTION\
            "This table contains the set of protocols supported by\
             neighboring Intermediate Systems as reported in received\
             IIH PDUs."\
    ::= { isisISAdj 4 }\
\
    isisISAdjProtSuppEntry OBJECT-TYPE\
        SYNTAX IsisISAdjProtSuppEntry\
        MAX-ACCESS not-accessible\
        STATUS current\
        DESCRIPTION\
            "Each entry contains one protocol supported by a\
             neighboring Intermediate System as reported in its IIH\
             PDUs.\
\
             Dynamically learned rows do not survive an agent reboot."\
        INDEX {  isisCircIndex,\
                 isisISAdjIndex,\
                 isisISAdjProtSuppProtocol }\
    ::= { isisISAdjProtSuppTable 1 }\
\
    IsisISAdjProtSuppEntry ::=\
        SEQUENCE {\
\
\
\
Parker                      Standards Track                    [Page 56]\
\
RFC 4444                       IS-IS MIB                      April 2006\
\
\
            isisISAdjProtSuppProtocol\
                IsisSupportedProtocol\
        }\
\
    isisISAdjProtSuppProtocol OBJECT-TYPE\
        SYNTAX IsisSupportedProtocol\
        MAX-ACCESS read-only\
        STATUS current\
        DESCRIPTION\
            "One supported protocol as reported in IIH PDUs received\
             from the neighbor."\
    ::= { isisISAdjProtSuppEntry 1 }\
\
-- The Reachable Address Group\
--\
-- The Reachable Address Table\
-- Each entry records information about a reachable address\
-- (NSAP or address prefix) manually configured on the system\
-- or learned through another protocol.\
\
    isisRATable OBJECT-TYPE\
        SYNTAX SEQUENCE OF IsisRAEntry\
        MAX-ACCESS not-accessible\
        STATUS current\
        DESCRIPTION\
            "The table of Reachable Addresses to NSAPs or Address\
             Prefixes."\
    ::= { isisReachAddr 1 }\
\
    isisRAEntry OBJECT-TYPE\
        SYNTAX IsisRAEntry\
        MAX-ACCESS not-accessible\
        STATUS current\
        DESCRIPTION\
            "Each entry defines a configured Reachable Address\
             to an NSAP or Address Prefix.\
\
             Dynamically created rows MUST survive an agent reboot."\
        INDEX { isisCircIndex,\
                isisRAIndex }\
    ::= { isisRATable 1 }\
\
    IsisRAEntry ::=\
        SEQUENCE {\
            isisRAIndex\
                Unsigned32,\
            isisRAExistState\
                RowStatus,\
\
\
\
Parker                      Standards Track                    [Page 57]\
\
RFC 4444                       IS-IS MIB                      April 2006\
\
\
            isisRAAdminState\
                IsisAdminState,\
            isisRAAddrPrefix\
                IsisOSINSAddress,\
            isisRAMapType\
                INTEGER,\
            isisRAMetric\
                IsisDefaultMetric,\
            isisRAMetricType\
                IsisMetricType,\
            isisRASNPAAddress\
                IsisOSINSAddress,\
            isisRASNPAMask\
                IsisOSINSAddress,\
            isisRASNPAPrefix\
                IsisOSINSAddress,\
            isisRAType\
                INTEGER\
        }\
\
    isisRAIndex OBJECT-TYPE\
        SYNTAX Unsigned32(1..4294967295)\
        MAX-ACCESS not-accessible\
        STATUS current\
        DESCRIPTION\
            "The identifier for this isisRAEntry.  This value must be\
             unique amongst all Reachable Addresses on the same parent\
             Circuit."\
    ::= { isisRAEntry 1 }\
\
    isisRAExistState OBJECT-TYPE\
        SYNTAX RowStatus\
        MAX-ACCESS read-create\
        STATUS current\
        DESCRIPTION\
            "The existence state of this Reachable Address.  This\
             object follows the ManualOrAutomatic behaviors.  Support\
             for 'createAndWait' and 'notInService' is not required.\
\
             A row entry cannot be modified when the value of this\
             object is 'active'."\
    ::= { isisRAEntry 2 }\
\
    isisRAAdminState OBJECT-TYPE\
        SYNTAX IsisAdminState\
        MAX-ACCESS read-create\
        STATUS current\
        DESCRIPTION\
\
\
\
Parker                      Standards Track                    [Page 58]\
\
RFC 4444                       IS-IS MIB                      April 2006\
\
\
            "The administrative state of the Reachable Address.  This\
             object follows the ManualOrAutomatic behaviors."\
        DEFVAL { off }\
    ::= { isisRAEntry 3 }\
\
    isisRAAddrPrefix OBJECT-TYPE\
        SYNTAX IsisOSINSAddress\
        MAX-ACCESS read-create\
        STATUS current\
        DESCRIPTION\
            "The destination of this Reachable Address.  This is an\
             Address Prefix.  This object follows the\
             ReplaceOnlyWhileDisabled and ManualOrAutomatic\
             behaviors."\
        REFERENCE "{ISIS.aoi addressPrefix (98)}"\
    ::= { isisRAEntry 4 }\
\
    isisRAMapType OBJECT-TYPE\
        SYNTAX INTEGER\
            {\
                none (1),\
                explicit (2),\
                extractIDI (3),\
                extractDSP (4)\
            }\
        MAX-ACCESS read-create\
        STATUS current\
        DESCRIPTION\
            "The type of mapping to be employed to ascertain the SNPA\
             Address that should be used in forwarding PDUs for this\
             Reachable Address prefix.  This object follows the\
             ManualOrAutomatic behavior.  The following values of\
             mapping type are defined:\
\
                 none: The mapping is null because the neighbor SNPA is\
                       implicit by nature of the subnetwork (e.g., a\
                       point-to-point linkage).\
\
                 explicit: The subnetwork addresses in the object\
                       isisRASNPAAddress are to be used.\
\
                 extractIDI: The SNPA is embedded in the IDI of\
                       the destination NSAP Address.  The mapping\
                       algorithm extracts the SNPA to be used\
                       according to the format and encoding rules of\
                       ISO8473/Add2.  This SNPA extraction algorithm can\
                       be used in conjunction with Reachable Address\
                       prefixes from the X.121, F.69, E.163, and E.164\
\
\
\
Parker                      Standards Track                    [Page 59]\
\
RFC 4444                       IS-IS MIB                      April 2006\
\
\
                       addressing subdomains.\
\
                 extractDSP: All, or a suffix, of the SNPA is embedded\
                       in the DSP of the destination address.  This SNPA\
                       extraction algorithm extracts the embedded\
                       subnetwork addressing information by performing a\
                       logical AND of the isisRASNPAMask object value\
                       with the destination address.  The part of the\
                       SNPA extracted from the destination NSAP is\
                       appended to the isisRASNPAPrefix object value to\
                       form the next hop subnetwork addressing\
                       information."\
\
        REFERENCE "{ISO10589-ISIS.aoi mappingType (107)}"\
    ::= { isisRAEntry 5 }\
\
    isisRAMetric OBJECT-TYPE\
        SYNTAX IsisDefaultMetric\
        MAX-ACCESS read-create\
        STATUS current\
        DESCRIPTION\
            "The metric value for reaching the specified\
             prefix over this circuit.  This object follows the\
             ManualOrAutomatic behavior."\
        REFERENCE "{ISIS.aoi DefaultMetric (99)}"\
        DEFVAL { 20 }\
    ::= { isisRAEntry 6 }\
\
    isisRAMetricType OBJECT-TYPE\
        SYNTAX IsisMetricType\
        MAX-ACCESS read-create\
        STATUS current\
        DESCRIPTION\
            "Indicates whether the metric is internal or\
             external.  This object follows the ManualOrAutomatic\
             behavior."\
        REFERENCE "{ISIS.aoi DefaultMetricType (103)}"\
        DEFVAL { internal }\
    ::= { isisRAEntry 7 }\
\
    isisRASNPAAddress OBJECT-TYPE\
        SYNTAX IsisOSINSAddress\
        MAX-ACCESS read-create\
        STATUS current\
        DESCRIPTION\
            "The SNPA Address to which a PDU may be forwarded in\
             order to reach a destination that matches the address\
             prefix of the Reachable Address.  This object follows the\
\
\
\
Parker                      Standards Track                    [Page 60]\
\
RFC 4444                       IS-IS MIB                      April 2006\
\
\
             ManualOrAutomatic behavior."\
        REFERENCE "{ISIS.aoi sNPAAddresses (109)}"\
-- Note only one address may be specified per Reachable Address\
-- in the MIB\
        DEFVAL { ''H }\
    ::= { isisRAEntry 8 }\
\
    isisRASNPAMask OBJECT-TYPE\
        SYNTAX IsisOSINSAddress\
        MAX-ACCESS read-create\
        STATUS current\
        DESCRIPTION\
            "A bit mask with 1 bit indicating the positions in the\
             effective destination address from which embedded SNPA\
             information is to be extracted.  For the extraction, the\
             first octet of the isisRASNPAMask object value is aligned\
             with the first octet (AFI) of the NSAP Address.  If the\
             isisRASNPAMask object value and NSAP Address are of\
             different lengths, the shorter of the two is logically\
             padded with zeros before performing the extraction.  This\
             object follows the ManualOrAutomatic behavior."\
        REFERENCE "{ISIS.aoi sNPAMask (122)}"\
        DEFVAL { '00'H }\
    ::= { isisRAEntry 9 }\
\
    isisRASNPAPrefix OBJECT-TYPE\
        SYNTAX IsisOSINSAddress\
        MAX-ACCESS read-create\
        STATUS current\
        DESCRIPTION\
            "A fixed SNPA prefix for use when the isisRAMapType is\
             extractDSP.  The SNPA Address to use is formed by\
             concatenating the fixed SNPA prefix with a variable SNPA\
             part that is extracted from the effective destination\
             address.  For Reachable Address prefixes in which the\
             entire SNPA is embedded in the DSP, the SNPA Prefix shall\
             be null.  This object follows the ManualOrAutomatic\
             behavior."\
        REFERENCE "{ISIS.aoi sNPAPrefix (123)}"\
        DEFVAL { '00'H }\
    ::= { isisRAEntry 10 }\
\
    isisRAType OBJECT-TYPE\
        SYNTAX INTEGER\
            {\
                manual (1),\
                automatic (2)\
            }\
\
\
\
Parker                      Standards Track                    [Page 61]\
\
RFC 4444                       IS-IS MIB                      April 2006\
\
\
        MAX-ACCESS read-create\
        STATUS current\
        DESCRIPTION\
            "The type of Reachable address.  Those of type\
             manual are created by the network manager.  Those\
             of type automatic are created through propagation\
             of routing information from another routing\
             protocol (e.g., IDRP). "\
        DEFVAL {manual}\
    ::= {isisRAEntry 11 }\
\
\
-- The IP Reachable Address Table\
\
-- Each entry records information about one IP reachable\
-- address manually configured on this system or learned from\
-- another protocol.\
\
    isisIPRATable OBJECT-TYPE\
        SYNTAX SEQUENCE OF IsisIPRAEntry\
        MAX-ACCESS not-accessible\
        STATUS current\
        DESCRIPTION\
            "The table of IP Reachable Addresses to networks,\
             subnetworks, or hosts either manually configured or\
             learned from another protocol."\
    ::= { isisIPReachAddr 1 }\
\
    isisIPRAEntry OBJECT-TYPE\
        SYNTAX IsisIPRAEntry\
        MAX-ACCESS not-accessible\
        STATUS current\
        DESCRIPTION\
            "Each entry defines an IP Reachable Address to a network,\
             subnetwork, or host.\
\
             Each IP Reachable Address may have multiple entries in the\
             table, one for each equal cost path to the reachable\
             address.\
\
             Dynamically created rows MUST survive an agent reboot.\
\
             Implementers need to be aware that if the total number\
             of elements (octets or sub-identifiers) in\
             isisIPRADestr, isisIPRADestPrefixLen, and\
             isisIPRANextHopIndex is too great, then OIDs of column\
             instances in this table will have more than 128\
             subidentifiers and cannot be accessed using SNMPv1,\
\
\
\
Parker                      Standards Track                    [Page 62]\
\
RFC 4444                       IS-IS MIB                      April 2006\
\
\
             SNMPv2c, or SNMPv3."\
        INDEX {  isisSysLevelIndex,\
                 isisIPRADestType,\
                 isisIPRADest,\
                 isisIPRADestPrefixLen,\
                 isisIPRANextHopIndex }\
    ::= { isisIPRATable 1 }\
\
    IsisIPRAEntry ::=\
        SEQUENCE {\
            isisIPRADestType\
                InetAddressType,\
            isisIPRADest\
                InetAddress,\
            isisIPRADestPrefixLen\
                InetAddressPrefixLength,\
            isisIPRANextHopIndex\
                Unsigned32,\
            isisIPRANextHopType\
                InetAddressType,\
            isisIPRANextHop\
                InetAddress,\
            isisIPRAType\
                INTEGER,\
            isisIPRAExistState\
                RowStatus,\
            isisIPRAAdminState\
                IsisAdminState,\
            isisIPRAMetric\
                IsisDefaultMetric,\
            isisIPRAMetricType\
                IsisMetricType,\
            isisIPRAFullMetric\
                IsisFullMetric,\
            isisIPRASNPAAddress\
                IsisOSINSAddress,\
            isisIPRASourceType\
                INTEGER\
        }\
\
    isisIPRADestType OBJECT-TYPE\
        SYNTAX InetAddressType\
        MAX-ACCESS not-accessible\
        STATUS current\
        DESCRIPTION\
            "The type of this IP Reachable Address."\
    ::= { isisIPRAEntry 1 }\
\
\
\
\
Parker                      Standards Track                    [Page 63]\
\
RFC 4444                       IS-IS MIB                      April 2006\
\
\
    isisIPRADest OBJECT-TYPE\
        SYNTAX InetAddress\
        MAX-ACCESS not-accessible\
        STATUS current\
        DESCRIPTION\
            "The destination of this IP Reachable Address.  This is\
             a network address, subnetwork address, or host\
             address.\
\
             The type of this address is determined by the value of\
             the isisIPRADestType object."\
\
    ::= { isisIPRAEntry 2 }\
\
    isisIPRADestPrefixLen OBJECT-TYPE\
        SYNTAX InetAddressPrefixLength\
        MAX-ACCESS not-accessible\
        STATUS current\
        DESCRIPTION\
            "The length of the IP Netmask for Reachability Address.\
\
             The values for the index objects isisIPRADest and\
             isisIPRADestPrefixLen must be consistent.  When the value\
             of isisIPRADest (excluding the zone index, if one\
             is present) is x, then the bitwise logical-AND\
             of x with the value of the mask formed from the\
             corresponding index object isisIPRADestPrefixLen MUST be\
             equal to x.  If not, then the index pair is not\
             consistent, and an inconsistentName error must be\
             returned on SET or CREATE requests."\
    ::= { isisIPRAEntry 3 }\
\
    isisIPRANextHopIndex OBJECT-TYPE\
        SYNTAX Unsigned32(1..4294967295)\
        MAX-ACCESS not-accessible\
        STATUS current\
        DESCRIPTION\
            "Index of next hop.  Used when there are multiple Equal\
             Cost Multipath alternatives for the same destination."\
    ::= { isisIPRAEntry 4 }\
\
    isisIPRANextHopType OBJECT-TYPE\
        SYNTAX InetAddressType\
        MAX-ACCESS read-create\
        STATUS current\
        DESCRIPTION\
            "The type of the IP next hop address."\
    ::= { isisIPRAEntry 5 }\
\
\
\
Parker                      Standards Track                    [Page 64]\
\
RFC 4444                       IS-IS MIB                      April 2006\
\
\
    isisIPRANextHop OBJECT-TYPE\
        SYNTAX InetAddress\
        MAX-ACCESS read-create\
        STATUS current\
        DESCRIPTION\
            "The IP next hop to this destination.\
\
             The type of this address is determined by the value of\
             the isisIPRANextHopType object."\
    ::= { isisIPRAEntry 6 }\
\
    isisIPRAType OBJECT-TYPE\
        SYNTAX INTEGER\
            {\
                manual (1),\
                automatic (2)\
            }\
        MAX-ACCESS read-create\
        STATUS current\
        DESCRIPTION\
            "The type of this IP Reachable Address.  Those of type\
             manual are created by the network manager.  Those of type\
             automatic are created through propagation of routing\
             information from another routing protocol.  This object\
             follows the ManualOrAutomatic behavior."\
    ::= { isisIPRAEntry 7 }\
\
    isisIPRAExistState OBJECT-TYPE\
        SYNTAX RowStatus\
        MAX-ACCESS read-create\
        STATUS current\
        DESCRIPTION\
            "The state of this IP Reachable Address.  This object\
             follows the ExistenceState and ManualOrAutomatic\
             behaviors.  Support for 'createAndWait' and\
             'notInService' is not required.\
\
             A row entry cannot be modified when the value of this\
             object is 'active'."\
    ::= { isisIPRAEntry 8 }\
\
    isisIPRAAdminState OBJECT-TYPE\
        SYNTAX IsisAdminState\
        MAX-ACCESS read-create\
        STATUS current\
        DESCRIPTION\
            "The administrative state of the IP Reachable Address.  This\
             object follows the IsisAdminState and ManualOrAutomatic\
\
\
\
Parker                      Standards Track                    [Page 65]\
\
RFC 4444                       IS-IS MIB                      April 2006\
\
\
             behaviors."\
        DEFVAL { off }\
    ::= { isisIPRAEntry 9 }\
\
    isisIPRAMetric OBJECT-TYPE\
        SYNTAX IsisDefaultMetric\
        MAX-ACCESS read-create\
        STATUS current\
        DESCRIPTION\
            "The metric value for reaching the specified\
             destination over this circuit.  This object follows the\
             ManualOrAutomatic behavior."\
        DEFVAL { 10 }\
    ::= { isisIPRAEntry 10 }\
\
    isisIPRAMetricType OBJECT-TYPE\
        SYNTAX IsisMetricType\
        MAX-ACCESS read-create\
        STATUS current\
        DESCRIPTION\
            "Indicates whether the metric is internal or\
             external.  This object follows the ManualOrAutomatic\
             behavior."\
        DEFVAL { internal }\
    ::= { isisIPRAEntry 11 }\
\
    isisIPRAFullMetric OBJECT-TYPE\
        SYNTAX IsisFullMetric\
        MAX-ACCESS read-create\
        STATUS current\
        DESCRIPTION\
            "The wide metric value for reaching the specified\
             destination over this circuit.  This object follows the\
             ManualOrAutomatic behavior."\
        DEFVAL { 10 }\
    ::= { isisIPRAEntry 12 }\
\
    isisIPRASNPAAddress OBJECT-TYPE\
        SYNTAX IsisOSINSAddress\
        MAX-ACCESS read-create\
        STATUS current\
        DESCRIPTION\
            "The SNPA Address to which a PDU may be forwarded in\
             order to reach a destination that matches this IP\
             Reachable Address.  This object follows the\
             ManualOrAutomatic behavior."\
        DEFVAL { ''H }\
    ::= { isisIPRAEntry 13 }\
\
\
\
Parker                      Standards Track                    [Page 66]\
\
RFC 4444                       IS-IS MIB                      April 2006\
\
\
    isisIPRASourceType OBJECT-TYPE\
        SYNTAX INTEGER\
            {\
                static (1),\
                direct (2),\
                ospfv2 (3),\
                ospfv3 (4),\
                isis   (5),\
                rip    (6),\
                igrp   (7),\
                eigrp  (8),\
                bgp    (9),\
                other (10)\
            }\
        MAX-ACCESS read-only\
        STATUS current\
        DESCRIPTION\
            "The origin of this route."\
    ::= { isisIPRAEntry 14 }\
\
-- The LSP Database Table\
--\
-- The first table provides Summary Information about LSPs\
-- The next table provides a complete record\
\
    isisLSPSummaryTable OBJECT-TYPE\
        SYNTAX SEQUENCE OF IsisLSPSummaryEntry\
        MAX-ACCESS not-accessible\
        STATUS current\
        DESCRIPTION\
            "The table of LSP Headers."\
    ::= { isisLSPDataBase 1 }\
\
    isisLSPSummaryEntry OBJECT-TYPE\
        SYNTAX IsisLSPSummaryEntry\
        MAX-ACCESS not-accessible\
        STATUS current\
        DESCRIPTION\
            "Each entry provides a summary describing an\
             LSP currently stored in the system.\
\
             Dynamically learned rows will not survive an\
             agent reboot."\
        INDEX {  isisLSPLevel,\
                 isisLSPID }\
    ::= { isisLSPSummaryTable 1 }\
\
    IsisLSPSummaryEntry ::=\
\
\
\
Parker                      Standards Track                    [Page 67]\
\
RFC 4444                       IS-IS MIB                      April 2006\
\
\
        SEQUENCE {\
            isisLSPLevel\
                IsisISLevel,\
            isisLSPID\
                IsisLinkStatePDUID,\
            isisLSPSeq\
                Unsigned32,\
            isisLSPZeroLife\
                TruthValue,\
            isisLSPChecksum\
                IsisUnsigned16TC,\
            isisLSPLifetimeRemain\
                IsisUnsigned16TC,\
            isisLSPPDULength\
                IsisUnsigned16TC,\
            isisLSPAttributes\
                IsisUnsigned8TC\
        }\
\
    isisLSPLevel OBJECT-TYPE\
        SYNTAX IsisISLevel\
        MAX-ACCESS not-accessible\
        STATUS current\
        DESCRIPTION\
            "At which level does this LSP appear?"\
    ::= { isisLSPSummaryEntry 1 }\
\
    isisLSPID OBJECT-TYPE\
        SYNTAX IsisLinkStatePDUID\
        MAX-ACCESS not-accessible\
        STATUS current\
        DESCRIPTION\
            "The 8-byte LSP ID for this Link State PDU."\
    ::= { isisLSPSummaryEntry 2 }\
\
    isisLSPSeq OBJECT-TYPE\
        SYNTAX Unsigned32\
        MAX-ACCESS read-only\
        STATUS current\
        DESCRIPTION\
            "The sequence number for this LSP."\
    ::= { isisLSPSummaryEntry 3 }\
\
    isisLSPZeroLife OBJECT-TYPE\
        SYNTAX TruthValue\
        MAX-ACCESS read-only\
        STATUS current\
        DESCRIPTION\
\
\
\
Parker                      Standards Track                    [Page 68]\
\
RFC 4444                       IS-IS MIB                      April 2006\
\
\
            "Is this LSP being purged by this system?"\
    ::= { isisLSPSummaryEntry 4 }\
\
    isisLSPChecksum OBJECT-TYPE\
        SYNTAX IsisUnsigned16TC\
        MAX-ACCESS read-only\
        STATUS current\
        DESCRIPTION\
            "The 16-bit Fletcher Checksum for this LSP."\
    ::= { isisLSPSummaryEntry 5 }\
\
    isisLSPLifetimeRemain OBJECT-TYPE\
        SYNTAX IsisUnsigned16TC\
        UNITS "seconds"\
        MAX-ACCESS read-only\
        STATUS current\
        DESCRIPTION\
            "The remaining lifetime, in seconds, for this LSP."\
    ::= { isisLSPSummaryEntry 6 }\
\
    isisLSPPDULength OBJECT-TYPE\
        SYNTAX IsisUnsigned16TC\
        MAX-ACCESS read-only\
        STATUS current\
        DESCRIPTION\
            "The length of this LSP."\
    ::= { isisLSPSummaryEntry 7 }\
\
    isisLSPAttributes OBJECT-TYPE\
        SYNTAX IsisUnsigned8TC\
        MAX-ACCESS read-only\
        STATUS current\
        DESCRIPTION\
            "Flags carried by the LSP."\
    ::= { isisLSPSummaryEntry 8 }\
\
-- LSP Table\
--\
-- The full LSP as a sequence of {Type, Len, Value} tuples\
-- Since the underlying LSP may have changed while downloading\
-- TLVs, we provide the Sequence number and Checksum for each\
-- LSP TLV, so the network manager may verify that they are\
-- still working on the same version of the LSP.\
\
    isisLSPTLVTable OBJECT-TYPE\
        SYNTAX SEQUENCE OF IsisLSPTLVEntry\
        MAX-ACCESS not-accessible\
        STATUS current\
\
\
\
Parker                      Standards Track                    [Page 69]\
\
RFC 4444                       IS-IS MIB                      April 2006\
\
\
        DESCRIPTION\
            "The table of LSPs in the database."\
    ::= { isisLSPDataBase 2 }\
\
    isisLSPTLVEntry OBJECT-TYPE\
        SYNTAX IsisLSPTLVEntry\
        MAX-ACCESS not-accessible\
        STATUS current\
        DESCRIPTION\
            "Each entry describes a TLV within\
             an LSP currently stored in the system.\
\
             Dynamically learned rows will not survive an\
             agent reboot."\
        INDEX {  isisLSPLevel,\
                 isisLSPID,\
                 isisLSPTLVIndex }\
    ::= { isisLSPTLVTable 1 }\
\
    IsisLSPTLVEntry ::=\
        SEQUENCE {\
            isisLSPTLVIndex\
                Unsigned32,\
            isisLSPTLVSeq\
                Unsigned32,\
            isisLSPTLVChecksum\
                IsisUnsigned16TC,\
            isisLSPTLVType\
                IsisUnsigned8TC,\
            isisLSPTLVLen\
                IsisUnsigned8TC,\
            isisLSPTLVValue\
                OCTET STRING\
        }\
\
    isisLSPTLVIndex OBJECT-TYPE\
        SYNTAX Unsigned32(1..4294967295)\
        MAX-ACCESS not-accessible\
        STATUS current\
        DESCRIPTION\
            "The index of this TLV in the LSP.  The first TLV has\
             index 1, and the Nth TLV has an index of N."\
    ::= { isisLSPTLVEntry 1 }\
\
    isisLSPTLVSeq OBJECT-TYPE\
        SYNTAX Unsigned32\
        MAX-ACCESS read-only\
        STATUS current\
\
\
\
Parker                      Standards Track                    [Page 70]\
\
RFC 4444                       IS-IS MIB                      April 2006\
\
\
        DESCRIPTION\
            "The sequence number for this LSP."\
    ::= { isisLSPTLVEntry 2 }\
\
    isisLSPTLVChecksum OBJECT-TYPE\
        SYNTAX IsisUnsigned16TC\
        MAX-ACCESS read-only\
        STATUS current\
        DESCRIPTION\
            "The 16-bit Fletcher Checksum for this LSP."\
    ::= { isisLSPTLVEntry 3 }\
\
    isisLSPTLVType OBJECT-TYPE\
        SYNTAX IsisUnsigned8TC\
        MAX-ACCESS read-only\
        STATUS current\
        DESCRIPTION\
            "The type of this TLV."\
    ::= { isisLSPTLVEntry 4 }\
\
    isisLSPTLVLen OBJECT-TYPE\
        SYNTAX IsisUnsigned8TC\
        MAX-ACCESS read-only\
        STATUS current\
        DESCRIPTION\
            "The length of this TLV."\
    ::= { isisLSPTLVEntry 5 }\
\
    isisLSPTLVValue OBJECT-TYPE\
        SYNTAX OCTET STRING (SIZE(0..255))\
        MAX-ACCESS read-only\
        STATUS current\
        DESCRIPTION\
            "The value of this TLV."\
    ::= { isisLSPTLVEntry 6 }\
\
\
-- The IS-IS Notification Table\
\
-- The IS-IS Notification Table records fields that are\
-- required for notifications\
\
    isisNotificationEntry OBJECT IDENTIFIER\
        ::= { isisNotification 1 }\
\
    isisNotificationSysLevelIndex OBJECT-TYPE\
        SYNTAX IsisLevel\
        MAX-ACCESS accessible-for-notify\
\
\
\
Parker                      Standards Track                    [Page 71]\
\
RFC 4444                       IS-IS MIB                      April 2006\
\
\
        STATUS current\
        DESCRIPTION\
            "The system level for this notification."\
    ::= { isisNotificationEntry 1 }\
\
    isisNotificationCircIfIndex OBJECT-TYPE\
        SYNTAX Unsigned32 (1..2147483647)\
        MAX-ACCESS accessible-for-notify\
        STATUS current\
        DESCRIPTION\
            "The identifier of this circuit relevant to\
             this notification."\
    ::= { isisNotificationEntry 2 }\
\
    isisPduLspId OBJECT-TYPE\
        SYNTAX IsisLinkStatePDUID\
        MAX-ACCESS accessible-for-notify\
        STATUS current\
        DESCRIPTION\
            "An Octet String that uniquely identifies\
             a Link State PDU."\
    ::= { isisNotificationEntry 3 }\
\
    isisPduFragment OBJECT-TYPE\
        SYNTAX IsisPDUHeader\
        MAX-ACCESS accessible-for-notify\
        STATUS current\
        DESCRIPTION\
            "Holds up to 64 initial bytes of a PDU that\
             triggered the notification."\
    ::= { isisNotificationEntry 4 }\
\
    isisPduFieldLen OBJECT-TYPE\
        SYNTAX IsisUnsigned8TC\
        MAX-ACCESS accessible-for-notify\
        STATUS current\
        DESCRIPTION\
            "Holds the System ID length reported in PDU we received."\
    ::= { isisNotificationEntry 5 }\
\
    isisPduMaxAreaAddress OBJECT-TYPE\
        SYNTAX IsisUnsigned8TC\
        MAX-ACCESS accessible-for-notify\
        STATUS current\
        DESCRIPTION\
            "Holds the Max Area Addresses reported in a PDU\
             we received."\
    ::= { isisNotificationEntry 6 }\
\
\
\
Parker                      Standards Track                    [Page 72]\
\
RFC 4444                       IS-IS MIB                      April 2006\
\
\
    isisPduProtocolVersion OBJECT-TYPE\
        SYNTAX IsisUnsigned8TC\
        MAX-ACCESS accessible-for-notify\
        STATUS current\
        DESCRIPTION\
            "Holds the Protocol version reported in PDU we received."\
    ::= { isisNotificationEntry 7 }\
\
    isisPduLspSize OBJECT-TYPE\
        SYNTAX Unsigned32 (0..2147483647)\
        MAX-ACCESS accessible-for-notify\
        STATUS current\
        DESCRIPTION\
            "Holds the size of LSP we received that is too\
             big to forward."\
    ::= { isisNotificationEntry 8 }\
\
    isisPduOriginatingBufferSize OBJECT-TYPE\
        SYNTAX IsisUnsigned16TC (0..16000)\
        MAX-ACCESS accessible-for-notify\
        STATUS current\
        DESCRIPTION\
            "Holds the size of isisSysLevelOrigLSPBuffSize advertised\
             by the peer in the originatingLSPBufferSize TLV.\
             If the peer does not advertise this TLV, this\
             value is set to 0."\
    ::= { isisNotificationEntry 9 }\
\
    isisPduBufferSize OBJECT-TYPE\
        SYNTAX IsisUnsigned16TC (0..16000)\
        MAX-ACCESS accessible-for-notify\
        STATUS current\
        DESCRIPTION\
            "Holds the size of LSP received from peer."\
    ::= { isisNotificationEntry 10 }\
\
    isisPduProtocolsSupported OBJECT-TYPE\
        SYNTAX OCTET STRING (SIZE(0..255))\
        MAX-ACCESS accessible-for-notify\
        STATUS current\
        DESCRIPTION\
            "The list of protocols supported by an\
             adjacent system.  This may be empty."\
    ::= { isisNotificationEntry 11 }\
\
    isisAdjState OBJECT-TYPE\
        SYNTAX INTEGER\
            {\
\
\
\
Parker                      Standards Track                    [Page 73]\
\
RFC 4444                       IS-IS MIB                      April 2006\
\
\
                 down (1),\
                 initializing (2),\
                 up (3),\
                 failed(4)\
            }\
        MAX-ACCESS accessible-for-notify\
        STATUS current\
        DESCRIPTION\
            "The current state of an adjacency."\
    ::= { isisNotificationEntry 12 }\
\
    isisErrorOffset OBJECT-TYPE\
        SYNTAX Unsigned32\
        MAX-ACCESS accessible-for-notify\
        STATUS current\
        DESCRIPTION\
            "An offset to a problem in a PDU.  If the problem\
             is a malformed TLV, this points to the beginning\
             of the TLV.  If the problem is in the header, this\
             points to the byte that is suspicious."\
    ::= { isisNotificationEntry 13 }\
\
    isisErrorTLVType OBJECT-TYPE\
        SYNTAX Unsigned32 (0..255)\
        MAX-ACCESS accessible-for-notify\
        STATUS current\
        DESCRIPTION\
             "The type for a malformed TLV."\
    ::= { isisNotificationEntry 14 }\
\
    isisNotificationAreaAddress OBJECT-TYPE\
        SYNTAX IsisOSINSAddress\
        MAX-ACCESS accessible-for-notify\
        STATUS current\
        DESCRIPTION\
            "An Area Address."\
    ::= { isisNotificationEntry 15 }\
\
-- Notification definitions\
--\
-- Note that notifications can be disabled by setting\
--     isisSysNotificationEnable false\
\
    isisDatabaseOverload NOTIFICATION-TYPE\
        OBJECTS {\
            isisNotificationSysLevelIndex,\
            isisSysLevelState\
        }\
\
\
\
Parker                      Standards Track                    [Page 74]\
\
RFC 4444                       IS-IS MIB                      April 2006\
\
\
        STATUS current\
        DESCRIPTION\
            "This notification is generated when the system\
             enters or leaves the Overload state.  The number\
             of times this has been generated and cleared is kept\
             track of by isisSysStatLSPDbaseOloads."\
    ::= { isisNotifications 1 }\
\
    isisManualAddressDrops NOTIFICATION-TYPE\
        OBJECTS {\
            isisNotificationAreaAddress\
        }\
        STATUS current\
        DESCRIPTION\
            "This notification is generated when one of the\
             manual areaAddresses assigned to this system is\
             ignored when computing routes.  The object\
             isisNotificationAreaAddress describes the area that\
             has been dropped.\
\
             The number of times this event has been generated\
             is counted by isisSysStatManAddrDropFromAreas.\
\
             The agent must throttle the generation of\
             consecutive isisManualAddressDrops notifications\
             so that there is at least a 5-second gap between\
             notifications of this type.  When notifications\
             are throttled, they are dropped, not queued for\
             sending at a future time."\
    ::= { isisNotifications 2 }\
\
    isisCorruptedLSPDetected NOTIFICATION-TYPE\
        OBJECTS {\
            isisNotificationSysLevelIndex,\
            isisPduLspId\
        }\
        STATUS current\
        DESCRIPTION\
            "This notification is generated when we find that\
             an LSP that was stored in memory has become\
             corrupted.  The number of times this has been\
             generated is counted by isisSysCorrLSPs.\
\
             We forward an LSP ID.  We may have independent\
             knowledge of the ID, but in some implementations\
             there is a chance that the ID itself will be\
             corrupted."\
\
\
\
\
Parker                      Standards Track                    [Page 75]\
\
RFC 4444                       IS-IS MIB                      April 2006\
\
\
    ::= { isisNotifications 3 }\
\
    isisAttemptToExceedMaxSequence NOTIFICATION-TYPE\
        OBJECTS {\
            isisNotificationSysLevelIndex,\
            isisPduLspId\
        }\
        STATUS current\
        DESCRIPTION\
            "When the sequence number on an LSP we generate\
             wraps the 32-bit sequence counter, we purge and\
             wait to re-announce this information.  This\
             notification describes that event.  Since these\
             should not be generated rapidly, we generate\
             an event each time this happens.\
\
             While the first 6 bytes of the LSPID are ours,\
             the other two contain useful information."\
\
    ::= { isisNotifications 4 }\
\
    isisIDLenMismatch  NOTIFICATION-TYPE\
        OBJECTS {\
            isisNotificationSysLevelIndex,\
            isisPduFieldLen,\
            isisNotificationCircIfIndex,\
            isisPduFragment\
        }\
        STATUS current\
        DESCRIPTION\
            "A notification sent when we receive a PDU\
             with a different value for the System ID Length.\
             This notification includes an index to identify\
             the circuit where we saw the PDU and the header of\
             the PDU, which may help a network manager identify\
             the source of the confusion.\
\
             The agent must throttle the generation of\
             consecutive isisIDLenMismatch notifications\
             so that there is at least a 5-second gap between\
             notifications of this type.  When notifications\
             are throttled, they are dropped, not queued for\
             sending at a future time."\
\
    ::= { isisNotifications 5 }\
\
    isisMaxAreaAddressesMismatch NOTIFICATION-TYPE\
        OBJECTS {\
\
\
\
Parker                      Standards Track                    [Page 76]\
\
RFC 4444                       IS-IS MIB                      April 2006\
\
\
            isisNotificationSysLevelIndex,\
            isisPduMaxAreaAddress,\
            isisNotificationCircIfIndex,\
            isisPduFragment\
        }\
\
        STATUS current\
        DESCRIPTION\
            "A notification sent when we receive a PDU\
             with a different value for the Maximum Area\
             Addresses.  This notification includes the\
             header of the packet, which may help a\
             network manager identify the source of the\
             confusion.\
\
             The agent must throttle the generation of\
             consecutive isisMaxAreaAddressesMismatch\
             notifications so that there is at least a 5-second\
             gap between notifications of this type.  When\
             notifications are throttled, they are dropped, not\
             queued for sending at a future time."\
\
    ::= { isisNotifications 6 }\
\
    isisOwnLSPPurge NOTIFICATION-TYPE\
        OBJECTS {\
            isisNotificationSysLevelIndex,\
            isisNotificationCircIfIndex,\
            isisPduLspId\
        }\
        STATUS current\
        DESCRIPTION\
            "A notification sent when we receive a PDU\
             with our systemID and zero age.  This\
             notification includes the circuit Index\
             and router ID from the LSP, if available,\
             which may help a network manager\
             identify the source of the confusion."\
\
    ::= { isisNotifications 7 }\
\
    isisSequenceNumberSkip NOTIFICATION-TYPE\
        OBJECTS {\
            isisNotificationSysLevelIndex,\
            isisNotificationCircIfIndex,\
            isisPduLspId\
        }\
        STATUS current\
\
\
\
Parker                      Standards Track                    [Page 77]\
\
RFC 4444                       IS-IS MIB                      April 2006\
\
\
        DESCRIPTION\
            "When we receive an LSP with our System ID\
             and different contents, we may need to reissue\
             the LSP with a higher sequence number.\
\
             We send this notification if we need to increase\
             the sequence number by more than one.  If two\
             Intermediate Systems are configured with the same\
             System ID, this notification will fire."\
\
    ::= { isisNotifications 8 }\
\
    isisAuthenticationTypeFailure NOTIFICATION-TYPE\
        OBJECTS {\
            isisNotificationSysLevelIndex,\
            isisNotificationCircIfIndex,\
            isisPduFragment\
        }\
        STATUS current\
        DESCRIPTION\
            "A notification sent when we receive a PDU\
             with the wrong authentication type field.\
             This notification includes the header of the\
             packet, which may help a network manager\
             identify the source of the confusion.\
\
             The agent must throttle the generation of\
             consecutive isisAuthenticationTypeFailure\
             notifications so that there is at least a 5-second\
             gap between notifications of this type.  When\
             notifications are throttled, they are dropped, not\
             queued for sending at a future time."\
\
    ::= { isisNotifications 9 }\
\
    isisAuthenticationFailure NOTIFICATION-TYPE\
        OBJECTS {\
            isisNotificationSysLevelIndex,\
            isisNotificationCircIfIndex,\
            isisPduFragment\
        }\
        STATUS current\
        DESCRIPTION\
            "A notification sent when we receive a PDU\
             with an incorrect authentication information\
             field.  This notification includes the header\
             of the packet, which may help a network manager\
             identify the source of the confusion.\
\
\
\
Parker                      Standards Track                    [Page 78]\
\
RFC 4444                       IS-IS MIB                      April 2006\
\
\
             The agent must throttle the generation of\
             consecutive isisAuthenticationFailure\
             notifications so that there is at least a 5-second\
             gap between notifications of this type.  When\
             notifications are throttled, they are dropped, not\
             queued for sending at a future time."\
\
    ::= { isisNotifications 10 }\
\
    isisVersionSkew NOTIFICATION-TYPE\
        OBJECTS {\
            isisNotificationSysLevelIndex,\
            isisNotificationCircIfIndex,\
            isisPduProtocolVersion,\
            isisPduFragment\
        }\
        STATUS current\
        DESCRIPTION\
            "A notification sent when we receive a Hello\
             PDU from an IS running a different version\
             of the protocol.  This notification includes\
             the header of the packet, which may help a\
             network manager identify the source of the\
             confusion.\
\
             The agent must throttle the generation of\
             consecutive isisVersionSkew notifications\
             so that there is at least a 5-second gap\
             between notifications of this type.  When\
             notifications are throttled, they are dropped, not\
             queued for sending at a future time."\
\
    ::= { isisNotifications 11 }\
\
    isisAreaMismatch NOTIFICATION-TYPE\
        OBJECTS {\
            isisNotificationCircIfIndex,\
            isisPduFragment\
        }\
        STATUS current\
        DESCRIPTION\
            "A notification sent when we receive a Hello\
             PDU from an IS that does not share any\
             area address.  This notification includes\
             the header of the packet, which may help a\
             network manager identify the source of the\
             confusion.\
\
\
\
\
Parker                      Standards Track                    [Page 79]\
\
RFC 4444                       IS-IS MIB                      April 2006\
\
\
             The agent must throttle the generation of\
             consecutive isisAreaMismatch notifications\
             so that there is at least a 5-second gap\
             between notifications of this type.  When\
             notifications are throttled, they are dropped, not\
             queued for sending at a future time."\
\
    ::= { isisNotifications 12 }\
\
    isisRejectedAdjacency NOTIFICATION-TYPE\
        OBJECTS {\
            isisNotificationSysLevelIndex,\
            isisNotificationCircIfIndex,\
            isisPduFragment\
        }\
        STATUS current\
        DESCRIPTION\
            "A notification sent when we receive a Hello\
             PDU from an IS but do not establish an\
             adjacency for some reason.\
\
             The agent must throttle the generation of\
             consecutive isisRejectedAdjacency notifications\
             so that there is at least a 5-second gap\
             between notifications of this type.  When\
             notifications are throttled, they are dropped, not\
             queued for sending at a future time."\
\
    ::= { isisNotifications 13 }\
\
    isisLSPTooLargeToPropagate NOTIFICATION-TYPE\
        OBJECTS {\
            isisNotificationSysLevelIndex,\
            isisNotificationCircIfIndex,\
            isisPduLspSize,\
            isisPduLspId\
        }\
        STATUS current\
        DESCRIPTION\
            "A notification sent when we attempt to propagate\
             an LSP that is larger than the dataLinkBlockSize\
             for the circuit.\
\
             The agent must throttle the generation of\
             consecutive isisLSPTooLargeToPropagate notifications\
             so that there is at least a 5-second gap\
             between notifications of this type.  When\
             notifications are throttled, they are dropped, not\
\
\
\
Parker                      Standards Track                    [Page 80]\
\
RFC 4444                       IS-IS MIB                      April 2006\
\
\
             queued for sending at a future time."\
\
    ::= { isisNotifications 14 }\
\
    isisOrigLSPBuffSizeMismatch NOTIFICATION-TYPE\
        OBJECTS {\
            isisNotificationSysLevelIndex,\
            isisNotificationCircIfIndex,\
            isisPduLspId,\
            isisPduOriginatingBufferSize,\
            isisPduBufferSize\
        }\
        STATUS current\
        DESCRIPTION\
            "A notification sent when a Level 1 LSP or Level\
             2 LSP is received that is larger than the local\
             value for isisSysLevelOrigLSPBuffSize, or when an\
             LSP is received that contains the supported Buffer Size\
             option and the value in the PDU option field does\
             not match the local value for isisSysLevelOrigLSPBuffSize.\
             We pass up the size from the option field and the\
             size of the LSP when one of them exceeds our configuration.\
\
             The agent must throttle the generation of\
             consecutive isisOrigLSPBuffSizeMismatch notifications\
             so that there is at least a 5-second gap\
             between notifications of this type.  When\
             notifications are throttled, they are dropped, not\
             queued for sending at a future time."\
\
    ::= { isisNotifications 15 }\
\
    isisProtocolsSupportedMismatch NOTIFICATION-TYPE\
        OBJECTS {\
            isisNotificationSysLevelIndex,\
            isisNotificationCircIfIndex,\
            isisPduProtocolsSupported,\
            isisPduLspId,\
            isisPduFragment\
        }\
        STATUS current\
        DESCRIPTION\
            "A notification sent when a non-pseudonode\
             segment 0 LSP is received that has no matching\
             protocols supported.  This may be because the system\
             does not generate the field, or because there are no\
             common elements.  The list of protocols supported\
             should be included in the notification: it may be\
\
\
\
Parker                      Standards Track                    [Page 81]\
\
RFC 4444                       IS-IS MIB                      April 2006\
\
\
             empty if the TLV is not supported, or if the\
             TLV is empty.\
\
             The agent must throttle the generation of\
             consecutive isisProtocolsSupportedMismatch\
             notifications so that there is at least a 5-second\
             gap between notifications of this type.  When\
             notifications are throttled, they are dropped, not\
             queued for sending at a future time."\
\
    ::= { isisNotifications 16 }\
\
    isisAdjacencyChange NOTIFICATION-TYPE\
        OBJECTS {\
            isisNotificationSysLevelIndex,\
            isisNotificationCircIfIndex,\
            isisPduLspId,\
            isisAdjState\
        }\
        STATUS current\
        DESCRIPTION\
            "A notification sent when an adjacency changes\
             state, entering or leaving state up.\
             The first 6 bytes of the isisPduLspId are the\
             SystemID of the adjacent IS.\
             The isisAdjState is the new state of the adjacency."\
\
    ::= { isisNotifications 17 }\
\
    isisLSPErrorDetected NOTIFICATION-TYPE\
        OBJECTS {\
            isisNotificationSysLevelIndex,\
            isisPduLspId,\
            isisNotificationCircIfIndex,\
            isisPduFragment,\
            isisErrorOffset,\
            isisErrorTLVType\
        }\
        STATUS current\
        DESCRIPTION\
            "This notification is generated when we receive\
             an LSP with a parse error.  The isisCircIfIndex\
             holds an index of the circuit on which the PDU\
             arrived.  The isisPduFragment holds the start of the\
             LSP, and the isisErrorOffset points to the problem.\
\
             If the problem is a malformed TLV, isisErrorOffset\
             points to the start of the TLV, and isisErrorTLVType\
\
\
\
Parker                      Standards Track                    [Page 82]\
\
RFC 4444                       IS-IS MIB                      April 2006\
\
\
             holds the value of the type.\
\
             If the problem is with the LSP header, isisErrorOffset\
             points to the suspicious byte.\
\
             The number of such LSPs is accumulated in\
             isisSysStatLSPErrors."\
\
    ::= { isisNotifications 18 }\
\
-- Agent Conformance Definitions\
-- We define the objects a conformant agent must define\
\
isisCompliances OBJECT IDENTIFIER ::= { isisConformance 1 }\
isisGroups      OBJECT IDENTIFIER ::= { isisConformance 2 }\
\
-- compliance statements\
\
    isisCompliance MODULE-COMPLIANCE\
        STATUS current\
        DESCRIPTION\
            "The compliance statement for agents that support\
             the IS-IS MIB.\
\
             There are a number of INDEX objects that cannot be\
             represented in the form of OBJECT clauses in SMIv2,\
             but for which there are compliance requirements.\
             Those requirements and similar requirements for\
             related objects are expressed below, in\
             pseudo-OBJECT clause form, in this description:\
\
             -- OBJECT isisSummAddressType\
             -- SYNTAX InetAddressType { ipv4(1), ipv6(2) }\
             --\
             -- DESCRIPTION\
             --    The MIB requires support for IPv4 Summary\
             --    Addresses and anticipates the support of\
             --    IPv6 addresses.\
             --\
             --\
             -- OBJECT isisRedistributeAddrType\
             -- SYNTAX InetAddressType { ipv4(1), ipv6(2) }\
             --\
             -- DESCRIPTION\
             --    The MIB requires support for IPv4\
             --    Redistribution Addresses and anticipates\
             --    the support of IPv6 addresses."\
             --\
\
\
\
Parker                      Standards Track                    [Page 83]\
\
RFC 4444                       IS-IS MIB                      April 2006\
\
\
             --\
             -- OBJECT isisISAdjIPAddrType\
             -- SYNTAX InetAddressType { ipv4(1), ipv6(2) }\
             --\
             -- DESCRIPTION\
             --    The MIB requires support for IPv4\
             --    Adjacency Addresses and anticipates the\
             --    support of IPv6 addresses.\
        MODULE -- this module\
            MANDATORY-GROUPS {\
                    isisSystemGroup,\
                    isisCircuitGroup,\
                    isisISAdjGroup,\
                    isisNotificationObjectGroup,\
                    isisNotificationGroup\
            }\
    ::= { isisCompliances 1 }\
\
    -- List of all groups, mandatory and optional\
    isisAdvancedCompliance MODULE-COMPLIANCE\
        STATUS current\
        DESCRIPTION\
            "The compliance statement for agents that fully\
             support the IS-IS MIB.\
\
             There are a number of INDEX objects that cannot be\
             represented in the form of OBJECT clauses in SMIv2,\
             but for which there are compliance requirements.\
             Those requirements and similar requirements for\
             related objects are expressed below, in\
             pseudo-OBJECT clause form, in this description:\
\
             -- OBJECT isisSummAddressType\
             -- SYNTAX InetAddressType { ipv4(1), ipv6(2) }\
             --\
             -- DESCRIPTION\
             --    The MIB requires support for IPv4 Summary\
             --    Addresses and anticipates the support of\
             --    IPv6 addresses.\
             --\
             --\
             -- OBJECT isisRedistributeAddrType\
             -- SYNTAX InetAddressType { ipv4(1), ipv6(2) }\
             --\
             -- DESCRIPTION\
             --    The MIB requires support for IPv4\
             --    Redistribution Addresses and anticipates\
             --    the support of IPv6 addresses."\
\
\
\
Parker                      Standards Track                    [Page 84]\
\
RFC 4444                       IS-IS MIB                      April 2006\
\
\
             --\
             --\
             -- OBJECT isisISAdjIPAddrType\
             -- SYNTAX InetAddressType { ipv4(1), ipv6(2) }\
             --\
             -- DESCRIPTION\
             --    The MIB requires support for IPv4\
             --    Adjacency Addresses and anticipates the\
             --    support of IPv6 addresses.\
             --\
             --\
             -- OBJECT isisIPRADestType\
             -- SYNTAX InetAddressType { ipv4(1), ipv6(2) }\
             --\
             -- DESCRIPTION\
             --    The MIB requires support for IPv4 RA\
             --    Addresses and anticipates the support of\
             --    IPv6 addresses.\
             --\
             --\
             -- OBJECT isisIPRANextHopType\
             -- SYNTAX InetAddressType { ipv4(1), ipv6(2) }\
             --\
             -- DESCRIPTION\
             --    The MIB requires support for IPv4 NextHop\
             --    Addresses and anticipates the support of\
             --    IPv6 addresses.\
        MODULE -- this module\
            MANDATORY-GROUPS {\
                    isisSystemGroup,\
                    isisCircuitGroup,\
                    isisISAdjGroup,\
                    isisNotificationObjectGroup,\
                    isisNotificationGroup,\
                    isisISPDUCounterGroup,\
                    isisRATableGroup,\
                    isisISIPRADestGroup,\
                    isisLSPGroup\
            }\
    ::= { isisCompliances 2 }\
\
    isisReadOnlyCompliance MODULE-COMPLIANCE\
       STATUS     current\
       DESCRIPTION\
               "When this MIB is implemented without support for\
                read-create (i.e., in read-only mode), the\
                implementation can claim read-only compliance.  Such\
                a device can then be monitored but cannot be\
\
\
\
Parker                      Standards Track                    [Page 85]\
\
RFC 4444                       IS-IS MIB                      April 2006\
\
\
                configured with this MIB."\
       MODULE -- this module\
            MANDATORY-GROUPS {\
                    isisSystemGroup,\
                    isisCircuitGroup,\
                    isisISAdjGroup\
            }\
\
       OBJECT isisSysLevelType\
       MIN-ACCESS read-only\
       DESCRIPTION\
            "Write access is not required."\
\
       OBJECT isisSysID\
       MIN-ACCESS read-only\
       DESCRIPTION\
            "Write access is not required."\
\
       OBJECT isisSysMaxPathSplits\
       MIN-ACCESS read-only\
       DESCRIPTION\
            "Write access is not required."\
\
       OBJECT isisSysMaxLSPGenInt\
       MIN-ACCESS read-only\
       DESCRIPTION\
            "Write access is not required."\
\
       OBJECT isisSysPollESHelloRate\
       MIN-ACCESS read-only\
       DESCRIPTION\
            "Write access is not required."\
\
       OBJECT isisSysWaitTime\
       MIN-ACCESS read-only\
       DESCRIPTION\
            "Write access is not required."\
\
       OBJECT isisSysAdminState\
       MIN-ACCESS read-only\
       DESCRIPTION\
            "Write access is not required."\
\
       OBJECT isisSysL2toL1Leaking\
       MIN-ACCESS read-only\
       DESCRIPTION\
            "Write access is not required."\
\
\
\
\
Parker                      Standards Track                    [Page 86]\
\
RFC 4444                       IS-IS MIB                      April 2006\
\
\
       OBJECT isisSysMaxAge\
       MIN-ACCESS read-only\
       DESCRIPTION\
            "Write access is not required."\
\
       OBJECT isisManAreaAddrExistState\
       MIN-ACCESS read-only\
       DESCRIPTION\
            "Write access is not required."\
\
       OBJECT isisSysLevelOrigLSPBuffSize\
       MIN-ACCESS read-only\
       DESCRIPTION\
            "Write access is not required."\
\
       OBJECT isisSysLevelMinLSPGenInt\
       MIN-ACCESS read-only\
       DESCRIPTION\
            "Write access is not required."\
\
       OBJECT isisSysLevelSetOverload\
       MIN-ACCESS read-only\
       DESCRIPTION\
            "Write access is not required."\
\
       OBJECT isisSysLevelSetOverloadUntil\
       MIN-ACCESS read-only\
       DESCRIPTION\
            "Write access is not required."\
\
       OBJECT isisSysLevelMetricStyle\
       MIN-ACCESS read-only\
       DESCRIPTION\
            "Write access is not required."\
\
       OBJECT isisSysLevelSPFConsiders\
       MIN-ACCESS read-only\
       DESCRIPTION\
            "Write access is not required."\
\
       OBJECT isisSysLevelTEEnabled\
       MIN-ACCESS read-only\
       DESCRIPTION\
            "Write access is not required."\
\
       OBJECT isisSysReceiveLSPBufferSize\
       MIN-ACCESS read-only\
       DESCRIPTION\
\
\
\
Parker                      Standards Track                    [Page 87]\
\
RFC 4444                       IS-IS MIB                      April 2006\
\
\
            "Write access is not required."\
\
       OBJECT isisSummAddrExistState\
       MIN-ACCESS read-only\
       DESCRIPTION\
            "Write access is not required."\
\
       OBJECT isisSummAddrMetric\
       MIN-ACCESS read-only\
       DESCRIPTION\
            "Write access is not required."\
\
       OBJECT isisSummAddrFullMetric\
       MIN-ACCESS read-only\
       DESCRIPTION\
            "Write access is not required."\
\
       OBJECT isisRedistributeAddrExistState\
       MIN-ACCESS read-only\
       DESCRIPTION\
            "Write access is not required."\
\
       OBJECT isisCircAdminState\
       MIN-ACCESS read-only\
       DESCRIPTION\
            "Write access is not required."\
\
       OBJECT isisCircExistState\
       MIN-ACCESS read-only\
       DESCRIPTION\
            "Write access is not required."\
\
       OBJECT isisCircType\
       MIN-ACCESS read-only\
       DESCRIPTION\
            "Write access is not required."\
\
       OBJECT isisCircExtDomain\
       MIN-ACCESS read-only\
       DESCRIPTION\
            "Write access is not required."\
\
       OBJECT isisCircLevelType\
       MIN-ACCESS read-only\
       DESCRIPTION\
            "Write access is not required."\
\
       OBJECT isisCircPassiveCircuit\
\
\
\
Parker                      Standards Track                    [Page 88]\
\
RFC 4444                       IS-IS MIB                      April 2006\
\
\
       MIN-ACCESS read-only\
       DESCRIPTION\
            "Write access is not required."\
\
       OBJECT isisCircMeshGroupEnabled\
       MIN-ACCESS read-only\
       DESCRIPTION\
            "Write access is not required."\
\
       OBJECT isisCircMeshGroup\
       MIN-ACCESS read-only\
       DESCRIPTION\
            "Write access is not required."\
\
       OBJECT isisCircSmallHellos\
       MIN-ACCESS read-only\
       DESCRIPTION\
            "Write access is not required."\
\
       OBJECT isisCircExtendedCircID\
       MIN-ACCESS read-only\
       DESCRIPTION\
            "Write access is not required."\
\
       OBJECT isisCircIfIndex\
       MIN-ACCESS read-only\
       DESCRIPTION\
            "Write access is not required."\
\
       OBJECT isisCirc3WayEnabled\
       MIN-ACCESS read-only\
       DESCRIPTION\
            "Write access is not required."\
\
       OBJECT isisCircLevelMetric\
       MIN-ACCESS read-only\
       DESCRIPTION\
            "Write access is not required."\
\
       OBJECT isisCircLevelWideMetric\
       MIN-ACCESS read-only\
       DESCRIPTION\
            "Write access is not required."\
\
       OBJECT isisCircLevelISPriority\
       MIN-ACCESS read-only\
       DESCRIPTION\
            "Write access is not required."\
\
\
\
Parker                      Standards Track                    [Page 89]\
\
RFC 4444                       IS-IS MIB                      April 2006\
\
\
       OBJECT isisCircLevelHelloMultiplier\
       MIN-ACCESS read-only\
       DESCRIPTION\
            "Write access is not required."\
\
       OBJECT isisCircLevelHelloTimer\
       MIN-ACCESS read-only\
       DESCRIPTION\
            "Write access is not required."\
\
       OBJECT isisCircLevelDRHelloTimer\
       MIN-ACCESS read-only\
       DESCRIPTION\
            "Write access is not required."\
\
       OBJECT isisCircLevelLSPThrottle\
       MIN-ACCESS read-only\
       DESCRIPTION\
            "Write access is not required."\
\
       OBJECT isisCircLevelMinLSPRetransInt\
       MIN-ACCESS read-only\
       DESCRIPTION\
            "Write access is not required."\
\
       OBJECT isisCircLevelCSNPInterval\
       MIN-ACCESS read-only\
       DESCRIPTION\
            "Write access is not required."\
\
       OBJECT isisCircLevelPartSNPInterval\
       MIN-ACCESS read-only\
       DESCRIPTION\
            "Write access is not required."\
\
    ::= { isisCompliances 3 }\
\
-- MIB Grouping\
\
    isisSystemGroup OBJECT-GROUP\
        OBJECTS {\
            isisSysVersion,\
            isisSysLevelType,\
            isisSysID,\
            isisSysMaxPathSplits,\
            isisSysMaxLSPGenInt,\
            isisSysPollESHelloRate,\
            isisSysWaitTime,\
\
\
\
Parker                      Standards Track                    [Page 90]\
\
RFC 4444                       IS-IS MIB                      April 2006\
\
\
            isisSysAdminState,\
            isisSysL2toL1Leaking,\
            isisSysMaxAge,\
            isisSysProtSupported,\
            isisSysNotificationEnable,\
            isisManAreaAddrExistState,\
            isisSysLevelOrigLSPBuffSize,\
            isisSysLevelMinLSPGenInt,\
            isisSysLevelState,\
            isisSysLevelSetOverload,\
            isisSysLevelSetOverloadUntil,\
            isisSysLevelMetricStyle,\
            isisSysLevelSPFConsiders,\
            isisSysLevelTEEnabled,\
            isisSysReceiveLSPBufferSize,\
            isisSummAddrExistState,\
            isisSummAddrMetric,\
            isisAreaAddr,\
            isisSummAddrFullMetric,\
            isisRedistributeAddrExistState,\
            isisRouterHostName,\
            isisRouterID,\
            isisSysStatCorrLSPs,\
            isisSysStatLSPDbaseOloads,\
            isisSysStatManAddrDropFromAreas,\
            isisSysStatAttmptToExMaxSeqNums,\
            isisSysStatSeqNumSkips,\
            isisSysStatOwnLSPPurges,\
            isisSysStatIDFieldLenMismatches,\
            isisSysStatPartChanges,\
            isisSysStatSPFRuns,\
            isisSysStatAuthTypeFails,\
            isisSysStatAuthFails,\
            isisSysStatLSPErrors\
        }\
        STATUS current\
        DESCRIPTION\
            "The collections of objects used to manage an\
             IS-IS router."\
    ::= { isisGroups 1 }\
\
    isisCircuitGroup OBJECT-GROUP\
        OBJECTS {\
            isisNextCircIndex,\
            isisCircAdminState,\
            isisCircExistState,\
            isisCircType,\
            isisCircExtDomain,\
\
\
\
Parker                      Standards Track                    [Page 91]\
\
RFC 4444                       IS-IS MIB                      April 2006\
\
\
            isisCircLevelType,\
            isisCircAdjChanges,\
            isisCircNumAdj,\
            isisCircInitFails,\
            isisCircRejAdjs,\
            isisCircIDFieldLenMismatches,\
            isisCircMaxAreaAddrMismatches,\
            isisCircAuthTypeFails,\
            isisCircAuthFails,\
            isisCircLANDesISChanges,\
            isisCircPassiveCircuit,\
            isisCircMeshGroupEnabled,\
            isisCircMeshGroup,\
            isisCircSmallHellos,\
            isisCircLastUpTime,\
            isisCirc3WayEnabled,\
            isisCircExtendedCircID,\
            isisCircIfIndex,\
            isisCircLevelMetric,\
            isisCircLevelWideMetric,\
            isisCircLevelISPriority,\
            isisCircLevelIDOctet,\
            isisCircLevelID,\
            isisCircLevelDesIS,\
            isisCircLevelHelloMultiplier,\
            isisCircLevelHelloTimer,\
            isisCircLevelDRHelloTimer,\
            isisCircLevelLSPThrottle,\
            isisCircLevelMinLSPRetransInt,\
            isisCircLevelCSNPInterval,\
            isisCircLevelPartSNPInterval\
        }\
        STATUS current\
        DESCRIPTION\
            "The collections of objects used to describe an\
             IS-IS Circuit."\
    ::= { isisGroups 2 }\
\
    isisISAdjGroup OBJECT-GROUP\
        OBJECTS {\
            isisISAdjState,\
            isisISAdj3WayState,\
            isisISAdjNeighSNPAAddress,\
            isisISAdjNeighSysType,\
            isisISAdjNeighSysID,\
            isisISAdjNbrExtendedCircID,\
            isisISAdjUsage,\
            isisISAdjHoldTimer,\
\
\
\
Parker                      Standards Track                    [Page 92]\
\
RFC 4444                       IS-IS MIB                      April 2006\
\
\
            isisISAdjNeighPriority,\
            isisISAdjLastUpTime,\
            isisISAdjAreaAddress,\
            isisISAdjIPAddrType,\
            isisISAdjIPAddrAddress,\
            isisISAdjProtSuppProtocol\
        }\
        STATUS current\
        DESCRIPTION\
            "The collections of objects used to manage an\
             IS-IS Adjacency."\
    ::= { isisGroups 3 }\
\
    isisNotificationObjectGroup OBJECT-GROUP\
        OBJECTS {\
            isisNotificationSysLevelIndex,\
            isisNotificationCircIfIndex,\
            isisPduLspId,\
            isisPduFragment,\
            isisPduFieldLen,\
            isisPduMaxAreaAddress,\
            isisPduProtocolVersion,\
            isisPduLspSize,\
            isisPduOriginatingBufferSize,\
            isisPduBufferSize,\
            isisPduProtocolsSupported,\
            isisAdjState,\
            isisErrorOffset,\
            isisErrorTLVType,\
            isisNotificationAreaAddress\
        }\
        STATUS current\
        DESCRIPTION\
            "The objects used to record notification parameters."\
    ::= { isisGroups 4 }\
\
\
    isisNotificationGroup        NOTIFICATION-GROUP\
        NOTIFICATIONS {\
            isisDatabaseOverload,\
            isisManualAddressDrops,\
            isisCorruptedLSPDetected,\
            isisAttemptToExceedMaxSequence,\
            isisIDLenMismatch,\
            isisMaxAreaAddressesMismatch,\
            isisOwnLSPPurge,\
            isisSequenceNumberSkip,\
            isisAuthenticationTypeFailure,\
\
\
\
Parker                      Standards Track                    [Page 93]\
\
RFC 4444                       IS-IS MIB                      April 2006\
\
\
            isisAuthenticationFailure,\
            isisVersionSkew,\
            isisAreaMismatch,\
            isisRejectedAdjacency,\
            isisLSPTooLargeToPropagate,\
            isisOrigLSPBuffSizeMismatch,\
            isisProtocolsSupportedMismatch,\
            isisAdjacencyChange,\
            isisLSPErrorDetected\
        }\
        STATUS current\
        DESCRIPTION\
            "The collections of notifications sent by an IS."\
    ::= { isisGroups 5 }\
\
\
    isisISPDUCounterGroup OBJECT-GROUP\
        OBJECTS {\
            isisPacketCountIIHello,\
            isisPacketCountISHello,\
            isisPacketCountESHello,\
            isisPacketCountLSP,\
            isisPacketCountCSNP,\
            isisPacketCountPSNP,\
            isisPacketCountUnknown\
        }\
        STATUS current\
        DESCRIPTION\
            "The collections of objects used to count protocol PDUs."\
    ::= { isisGroups 6 }\
\
\
    isisRATableGroup OBJECT-GROUP\
        OBJECTS {\
            isisRAExistState,\
            isisRAAdminState,\
            isisRAAddrPrefix,\
            isisRAMapType,\
            isisRAMetric,\
            isisRAMetricType,\
            isisRASNPAAddress,\
            isisRASNPAMask,\
            isisRASNPAPrefix,\
            isisRAType\
        }\
        STATUS current\
        DESCRIPTION\
            "The collections of objects used to manage the\
\
\
\
Parker                      Standards Track                    [Page 94]\
\
RFC 4444                       IS-IS MIB                      April 2006\
\
\
             reachable NSAP prefixes."\
    ::= { isisGroups 7 }\
\
\
    isisISIPRADestGroup OBJECT-GROUP\
        OBJECTS {\
            isisIPRANextHopType,\
            isisIPRANextHop,\
            isisIPRAType,\
            isisIPRAExistState,\
            isisIPRAAdminState,\
            isisIPRAMetric,\
            isisIPRAFullMetric,\
            isisIPRAMetricType,\
            isisIPRASNPAAddress,\
            isisIPRASourceType\
        }\
        STATUS current\
        DESCRIPTION\
            "The collections of objects used to manage configured\
             IP addresses."\
    ::= { isisGroups 8 }\
\
    isisLSPGroup OBJECT-GROUP\
        OBJECTS {\
            isisLSPSeq,\
            isisLSPZeroLife,\
            isisLSPChecksum,\
            isisLSPLifetimeRemain,\
            isisLSPPDULength,\
            isisLSPAttributes,\
            isisLSPTLVSeq,\
            isisLSPTLVChecksum,\
            isisLSPTLVType,\
            isisLSPTLVLen,\
            isisLSPTLVValue\
        }\
        STATUS current\
        DESCRIPTION\
            "The collections of objects used to observe the LSP\
             Database."\
    ::= { isisGroups 9 }\
\
END\
\
\
\
\
\
\
\
Parker                      Standards Track                    [Page 95]\
\
RFC 4444                       IS-IS MIB                      April 2006\
\
\
5.  IANA Considerations\
\
   The MIB module in this document uses the following IANA-assigned\
   OBJECT IDENTIFIER values recorded in the SMI Numbers registry:\
\
      Descriptor        OBJECT IDENTIFIER value\
      ----------        -----------------------\
\
      isisMIB           { mib-2 138 }\
\
6.  Acknowledgements\
\
   This MIB is based on a March 1994 document by Chris Gunner, who\
   should be held blameless for the errors introduced since then.  This\
   version has been modified to include MIB-II syntax, to exclude\
   portions of the protocol that are not relevant to IP, such as the\
   ES-IS protocol, and to add management support for current practice.\
\
   We would like to thank the following individuals for constructive and\
   valuable comments: Mike Bartlett, Neal Castagnoli, Ken Chapman, Joan\
   Cucchiara, Satish Dattatri, Nagi Jonnala, Adrian Farrel, Shamik\
   Ganguly, Les Ginsberg, Don Goodspeed, Jeff Gross, Jim Halpin, Jon\
   Harrison, Dimitri Haskin, C. M. Heard, Peter Higginson, Christian\
   Hopps, Laura Liu, Gavin McPherson, Kay Noguchi, Serge Maskalik, Z.\
   Opalka, Jeff Pickering, Sundar Ramachandran, Swaminatha Ramalingam,\
   Aravind Ravikumar, Juergen Schoenwaelder, Koen Vermeulen, Hans De\
   Vleeschouwer, Bert Wijnen, and Bingzhang Zhao.\
\
7.  Security Considerations\
\
   Management information defined in this MIB may be considered\
   sensitive in some network environments.\
\
7.1.  Discussion\
\
   This MIB may be used to manage an IP router, which is used to direct\
   network traffic.  The control of network traffic allows an attacker\
   to deny service to a region of the network or to forward traffic to\
   adversaries.  By raising or lowering metrics, traffic may be directed\
   to insecure portions of the network.  By disabling the protocol on an\
   interface, the network may be partitioned.  Changes to the network\
   topology will force all routers to recompute their routes.  Periodic\
   route changes have brought down networks in the past by subjecting\
   routers to stressful recomputations.\
\
   There are a number of management objects defined in this MIB that\
   have a MAX-ACCESS clause of read-write and/or read-create.  Such\
   objects may be considered sensitive or vulnerable in some network\
\
\
\
Parker                      Standards Track                    [Page 96]\
\
RFC 4444                       IS-IS MIB                      April 2006\
\
\
   environments.  The support for SET operations in a non-secure\
   environment without proper protection can have a negative effect on\
   network operations.  Authentication of received SNMP requests and\
   controlled access to management information should be employed in\
   such environments.\
\
   We identify a set of threats and then list attributes that can be\
   used in each form of attack.  We discuss the effects that can be\
   obtained by a single change to the variable in each class.\
\
7.2.  Threats\
\
      - Drop an Adjacency\
      - Drop all Peers\
      - Drop Subnetwork\
      - Split the Network\
      - Intermittent Outages\
      - Redirect Traffic\
      - Delay Convergence\
      - Avoid Detection\
      - Prevent Updates\
      - Hijack LAN\
      - Create Problems for CLNS Networks\
\
7.2.1.  Drop an Adjacency\
\
   By changing attributes that are used to peer, we can disrupt an\
   adjacency and bring a link down.\
\
      isisCirc3WayEnabled\
      isisCircAdminState\
      isisCircExistState\
      isisCircLevelDRHelloTimer\
      isisCircLevelHelloTimer\
      isisCircLevelType\
      isisCircSmallHellos\
\
7.2.2.  Drop All Adjacencies\
\
   These attributes can be used to break some or all of a router's\
   adjacencies.  In the case of System ID, the adjacency may be\
   restored.  However, it will subject the network to additional stress.\
\
      isisSysLevelType\
      isisManAreaAddrExistState\
      isisSysAdminState\
      isisSysID\
\
\
\
\
Parker                      Standards Track                    [Page 97]\
\
RFC 4444                       IS-IS MIB                      April 2006\
\
\
7.2.3.  Drop Subnetwork\
\
   This attribute can be used to stop advertisement of a subnetwork\
   reachable through a single interface.\
\
      isisCircPassiveCircuit\
\
7.2.4.  Split the Network\
\
   If the network design depends upon Wide Metrics or TE, we can use\
   these attributes to prevent traffic from passing through a router.\
\
      isisSysLevelMetricStyle\
      isisSysLevelOrigLSPBuffSize\
      isisSysLevelSPFConsiders\
      isisSysLevelTEEnabled\
      isisSysReceiveLSPBufferSize\
\
7.2.5.  Intermittent Outages\
\
   We can use these attributes to subject the network to a series of\
   topology changes, or otherwise force extensive recomputations of\
   routes.\
\
      isisSysLevelMinLSPGenInt\
      isisSysLevelSetOverload\
      isisSysLevelSetOverloadUntil\
      isisSysMaxAge\
      isisSysMaxLSPGenInt\
      isisSysL2toL1Leaking\
      isisSysID\
\
7.2.6.  Redirect Traffic\
\
   By changing attributes such as metrics, we can push traffic to\
   different parts of the network.  This may allow an intruder to\
   observe data traffic from otherwise remote parts of the network.\
\
   We may also use these attributes to deny service to parts of the\
   network.\
\
      isisSysMaxPathSplits\
      isisCircLevelMetric\
      isisCircLevelWideMetric\
      isisIPRAAdminState\
      isisIPRAExistState\
      isisIPRAFullMetric\
      isisIPRAMetric\
\
\
\
Parker                      Standards Track                    [Page 98]\
\
RFC 4444                       IS-IS MIB                      April 2006\
\
\
      isisIPRAMetricType\
      isisIPRANextHop\
      isisIPRANextHopType\
      isisIPRASNPAAddress\
      isisIPRAType\
      isisRedistributeAddrExistState\
      isisSummAddrExistState\
      isisSummAddrFullMetric\
      isisSummAddrMetric\
      isisSysL2toL1Leaking\
\
7.2.7.  Delay Convergence\
\
   These attributes can be used to slow convergence by increasing the\
   minimal interval required to update a packet.\
\
      isisCircLevelCSNPInterval\
      isisCircLevelLSPThrottle\
      isisCircLevelMinLSPRetransInt\
      isisCircLevelPartSNPInterval\
      isisSysWaitTime\
      isisCircPassiveCircuit\
\
7.2.8.  Avoid Detection\
\
   By turning off traps, we can prevent a Network Management station\
   from observing problems in the network caused by other aspects of an\
   attack.\
\
      isisSysNotificationEnable\
\
7.2.9.  Prevent Updates\
\
   Mesh Groups can be used to prevent the transmission of Link State\
   PDUs on certain interfaces, delaying or preventing the propagation of\
   updates.\
\
      isisCircMeshGroup\
      isisCircMeshGroupEnabled\
\
7.2.10. Hijack LAN\
\
   If we have compromised a router, we can use this attribute to become\
   the designated router and lie about the topology of a LAN.\
\
      isisCircLevelISPriority\
\
\
\
\
\
Parker                      Standards Track                    [Page 99]\
\
RFC 4444                       IS-IS MIB                      April 2006\
\
\
7.2.11.  Create Problems for CLNS Networks\
\
   This attribute can be used to modify the handling of CLNS traffic.\
\
      isisRAAddrPrefix\
      isisRAAdminState\
      isisRAExistState\
      isisRAMapType\
      isisRAMetric\
      isisRAMetricType\
      isisRASNPAAddress\
      isisRASNPAMask\
      isisRASNPAPrefix\
      isisRAType\
      isisSysPollESHelloRate\
\
7.2.12.  Mostly Harmless\
\
   The following writable attributes do not pose a known security risk.\
\
      isisCircExtDomain\
      isisCircExtendedCircID\
      isisCircIfIndex\
      isisCircLevelHelloMultiplier\
      isisCircType\
\
7.2.13.  Recommendations\
\
   Much of the MIB is used to set or read attributes which are readily\
   visible to any intruder who has access to traffic.  None of the\
   security attributes are setable or visible through the MIB.  Read\
   access to the MIB does not pose additional risks or vulnerabilities.\
\
   If write access is to be provided, it is RECOMMENDED that\
   implementers consider the security features as provided by the SNMPv3\
   framework (see [RFC3410], section 8), including full support for the\
   SNMPv3 cryptographic mechanisms (for authentication and privacy).\
\
   SNMP versions prior to SNMPv3 did not include adequate security.\
   Even if the network itself is secure (for example by using IPSec),\
   even then, there is no control as to who on the secure network is\
   allowed to access and GET/SET (read/change/create/delete) the objects\
   in this MIB module.\
\
   Deployment of SNMP versions prior to SNMPv3 is NOT RECOMMENDED.\
   Instead, it is RECOMMENDED to deploy SNMPv3 and to enable\
   cryptographic security.  It is then a customer/operator\
   responsibility to ensure that the SNMP entity giving access to an\
\
\
\
Parker                      Standards Track                   [Page 100]\
\
RFC 4444                       IS-IS MIB                      April 2006\
\
\
   instance of this MIB module is properly configured to give access to\
   the objects only to those principals (users) that have legitimate\
   rights to indeed GET or SET (change/create/delete) them.\
\
8.  Normative References\
\
   [ISO10589] ISO 10589, "Intermediate system to Intermediate system\
              routeing information exchange protocol for use in\
              conjunction with the Protocol for providing the\
              Connectionless-mode Network Service (ISO 8473)," ISO/IEC\
              10589:2002.\
\
   [ISO10733] ISO 10733, "Information Processing Systems - Open Systems\
              Interconnection - Specification of the elements of\
              Management Information related to OSI Network layer\
              Standards", September 1998.\
\
   [RFC2119]  Bradner, S., "Key words for use in RFCs to Indicate\
              Requirement Levels", BCP 14, RFC 2119, March 1997.\
\
   [RFC1195]  Callon, R., "Use of OSI IS-IS for routing in TCP/IP and\
              dual environments", RFC 1195, December 1990.\
\
   [RFC2863]  McCloghrie, K. and F. Kastenholz, "The Interfaces Group\
              MIB", RFC 2863, June 2000.\
\
   [RFC3289]  Baker, F., Chan, K., and A. Smith, "Management Information\
              Base for the Differentiated Services Architecture", RFC\
              3289, May 2002.\
\
   [RFC3411]  Harrington, D., Presuhn, R., and B. Wijnen, "An\
              Architecture for Describing Simple Network Management\
              Protocol (SNMP) Management Frameworks", STD 62, RFC 3411,\
              December 2002.\
\
   [RFC2578]  McCloghrie, K., Perkins, D., and J. Schoenwaelder,\
              "Structure of Management Information Version 2 (SMIv2)",\
              STD 58, RFC 2578, April 1999.\
\
   [RFC2579]  McCloghrie, K., Perkins, D., and J. Schoenwaelder,\
              "Textual Conventions for SMIv2", STD 58, RFC 2579, April\
              1999.\
\
   [RFC2580]  McCloghrie, K., Perkins, D., and J. Schoenwaelder,\
              "Conformance Statements for SMIv2", STD 58, RFC 2580,\
              April 1999.\
\
\
\
\
\
Parker                      Standards Track                   [Page 101]\
\
RFC 4444                       IS-IS MIB                      April 2006\
\
\
   [RFC4001]  Daniele, M., Haberman, B., Routhier, S., and J.\
              Schoenwaelder, "Textual Conventions for Internet Network\
              Addresses", RFC 4001, February 2005.\
\
9.  Informative References\
\
   [RFC2973]  Balay, R., Katz, D., and J. Parker, "IS-IS Mesh Groups",\
              RFC 2973, October 2000.\
\
   [RFC3373]  Katz, D. and R. Saluja, "Three-Way Handshake for\
              Intermediate System to Intermediate System (IS-IS) Point-\
              to-Point Adjacencies", RFC 3373, September 2002.\
\
   [RFC3410]  Case, J., Mundy, R., Partain, D., and B. Stewart,\
              "Introduction and Applicability Statements for Internet-\
              Standard Management Framework", RFC 3410, December 2002.\
\
Authors' Address\
\
   Jeff Parker\
   Department of Computer Science\
   Middlebury College,\
   Middlebury, Vermont 05753\
\
   EMail: jeffp@middlebury.edu\
\
\
\
\
\
\
\
\
\
\
\
\
\
\
\
\
\
\
\
\
\
\
\
\
\
\
Parker                      Standards Track                   [Page 102]\
\
RFC 4444                       IS-IS MIB                      April 2006\
\
\
Full Copyright Statement\
\
   Copyright (C) The Internet Society (2006).\
\
   This document is subject to the rights, licenses and restrictions\
   contained in BCP 78, and except as set forth therein, the authors\
   retain all their rights.\
\
   This document and the information contained herein are provided on an\
   "AS IS" basis and THE CONTRIBUTOR, THE ORGANIZATION HE/SHE REPRESENTS\
   OR IS SPONSORED BY (IF ANY), THE INTERNET SOCIETY AND THE INTERNET\
   ENGINEERING TASK FORCE DISCLAIM ALL WARRANTIES, EXPRESS OR IMPLIED,\
   INCLUDING BUT NOT LIMITED TO ANY WARRANTY THAT THE USE OF THE\
   INFORMATION HEREIN WILL NOT INFRINGE ANY RIGHTS OR ANY IMPLIED\
   WARRANTIES OF MERCHANTABILITY OR FITNESS FOR A PARTICULAR PURPOSE.\
\
Intellectual Property\
\
   The IETF takes no position regarding the validity or scope of any\
   Intellectual Property Rights or other rights that might be claimed to\
   pertain to the implementation or use of the technology described in\
   this document or the extent to which any license under such rights\
   might or might not be available; nor does it represent that it has\
   made any independent effort to identify any such rights.  Information\
   on the procedures with respect to rights in RFC documents can be\
   found in BCP 78 and BCP 79.\
\
   Copies of IPR disclosures made to the IETF Secretariat and any\
   assurances of licenses to be made available, or the result of an\
   attempt made to obtain a general license or permission for the use of\
   such proprietary rights by implementers or users of this\
   specification can be obtained from the IETF on-line IPR repository at\
   http://www.ietf.org/ipr.\
\
   The IETF invites any interested party to bring to its attention any\
   copyrights, patents or patent applications, or other proprietary\
   rights that may cover technology that may be required to implement\
   this standard.  Please address the information to the IETF at\
   ietf-ipr@ietf.org.\
\
Acknowledgement\
\
   Funding for the RFC Editor function is provided by the IETF\
   Administrative Support Activity (IASA).\
\
\
\
\
\
\
\
Parker                      Standards Track                   [Page 103]\
\

doc 1
  field 0
    name titolo
    type string
    value rfc4447.txt
  field 1
    name contenuto
    type string
    value \
\
\
\
\
\
Network Working Group                                    L. Martini, Ed.\
Request for Comments: 4447                                      E. Rosen\
Category: Standards Track                            Cisco Systems, Inc.\
                                                             N. El-Aawar\
                                            Level 3 Communications, LLC.\
                                                                T. Smith\
                                                 Network Appliance, Inc.\
                                                                G. Heron\
                                                                 Tellabs\
                                                              April 2006\
\
\
                    Pseudowire Setup and Maintenance\
              Using the Label Distribution Protocol (LDP)\
\
Status of This Memo\
\
   This document specifies an Internet standards track protocol for the\
   Internet community, and requests discussion and suggestions for\
   improvements.  Please refer to the current edition of the "Internet\
   Official Protocol Standards" (STD 1) for the standardization state\
   and status of this protocol.  Distribution of this memo is unlimited.\
\
Copyright Notice\
\
   Copyright (C) The Internet Society (2006).\
\
Abstract\
\
   Layer 2 services (such as Frame Relay, Asynchronous Transfer Mode,\
   and Ethernet) can be "emulated" over an MPLS backbone by\
   encapsulating the Layer 2 Protocol Data Units (PDU) and transmitting\
   them over "pseudowires".  It is also possible to use pseudowires to\
   provide low-rate Time Division Multiplexed and a Synchronous Optical\
   NETworking circuit emulation over an MPLS-enabled network.  This\
   document specifies a protocol for establishing and maintaining the\
   pseudowires, using extensions to Label Distribution Protocol (LDP).\
   Procedures for encapsulating Layer 2 PDUs are specified in a set of\
   companion documents.\
\
\
\
\
\
\
\
\
\
\
\
\
Martini, et al.             Standards Track                     [Page 1]\
\
RFC 4447                     PWE3 Using LDP                   April 2006\
\
\
Table of Contents\
\
   1. Introduction ....................................................3\
   2. Specification of Requirements ...................................5\
   3. The Pseudowire Label ............................................5\
   4. Details Specific to Particular Emulated Services ................7\
      4.1. IP Layer 2 Transport .......................................7\
   5. LDP .............................................................7\
      5.1. LDP Extensions .............................................8\
      5.2. The PWid FEC Element .......................................8\
      5.3. The Generalized PWid FEC Element ..........................10\
           5.3.1. Attachment Identifiers .............................11\
           5.3.2. Encoding the Generalized ID FEC Element ............13\
                  5.3.2.1. Interface Parameters TLV ..................14\
                  5.3.2.2. PW Grouping TLV ...........................14\
           5.3.3. Signaling Procedures ...............................15\
      5.4. Signaling of Pseudowire Status ............................16\
           5.4.1. Use of Label Mappings Messages .....................16\
           5.4.2. Signaling PW Status ................................17\
           5.4.3. Pseudowire Status Negotiation Procedures ...........18\
      5.5. Interface Parameters Sub-TLV ..............................19\
   6. Control Word ...................................................20\
      6.1. PW Types for Which the Control Word is REQUIRED ...........20\
      6.2. PW Types for Which the Control Word is NOT Mandatory ......21\
      6.3. LDP Label Withdrawal Procedures ...........................22\
      6.4. Sequencing Considerations .................................23\
           6.4.1. Label Advertisements ...............................23\
           6.4.2. Label Release ......................................24\
   7. IANA Considerations ............................................24\
      7.1. LDP TLV TYPE ..............................................24\
      7.2. LDP Status Codes ..........................................24\
      7.3. FEC Type Name Space .......................................25\
   8. Security Considerations ........................................25\
      8.1. Data-Plane Security .......................................25\
      8.2. Control-Plane Security ....................................26\
   9. Acknowledgements ...............................................27\
   10. Normative References ..........................................27\
   11. Informative References ........................................27\
   12. Additional Contributing Authors ...............................28\
   Appendix A. C-bit Handling Procedures Diagram .....................31\
\
\
\
\
\
\
\
\
\
\
\
Martini, et al.             Standards Track                     [Page 2]\
\
RFC 4447                     PWE3 Using LDP                   April 2006\
\
\
1.  Introduction\
\
   In [FRAME], [ATM], [PPPHDLC], and [ETH], it is explained how to\
   encapsulate a Layer 2 Protocol Data Unit (PDU) for transmission over\
   an MPLS-enabled network.  Those documents specify that a "pseudowire\
   header", consisting of a demultiplexor field, will be prepended to\
   the encapsulated PDU.  The pseudowire demultiplexor field is\
   prepended before transmitting a packet on a pseudowire.  When the\
   packet arrives at the remote endpoint of the pseudowire, the\
   demultiplexor is what enables the receiver to identify the particular\
   pseudowire on which the packet has arrived.  To transmit the packet\
   from one pseudowire endpoint to another, the packet may need to\
   travel through a "Packet Switched Network (PSN) tunnel"; this will\
   require that an additional header be prepended to the packet.\
\
   Accompanying documents [CEP, SAToP] specify methods for transporting\
   time-division multiplexing (TDM) digital signals (TDM circuit\
   emulation) over a packet-oriented MPLS-enabled network.  The\
   transmission system for circuit-oriented TDM signals is the\
   Synchronous Optical Network (SONET)[SDH]/Synchronous Digital\
   Hierarchy (SDH) [ITUG].  To support TDM traffic, which includes\
   voice, data, and private leased-line service, the pseudowires must\
   emulate the circuit characteristics of SONET/SDH payloads.  The TDM\
   signals and payloads are encapsulated for transmission over\
   pseudowires.  A pseudowire demultiplexor and a PSN tunnel header is\
   prepended to this encapsulation.\
\
   [SAToP] describes methods for transporting low-rate time-division\
   multiplexing (TDM) digital signals (TDM circuit emulation) over PSNs,\
   while [CEP] similarly describes transport of high-rate TDM\
   (SONET/SDH).  To support TDM traffic, the pseudowires must emulate\
   the circuit characteristics of the original T1, E1, T3, E3, SONET, or\
   SDH signals.  [SAToP] does this by encapsulating an arbitrary but\
   constant amount of the TDM data in each packet, and the other methods\
   encapsulate TDM structures.\
\
   In this document, we specify the use of the MPLS Label Distribution\
   Protocol, LDP [RFC3036], as a protocol for setting up and maintaining\
   the pseudowires.  In particular, we define new TLVs, FEC elements,\
   parameters, and codes for LDP, which enable LDP to identify\
   pseudowires and to signal attributes of pseudowires.  We specify how\
   a pseudowire endpoint uses these TLVs in LDP to bind a demultiplexor\
   field value to a pseudowire, and how it informs the remote endpoint\
   of the binding.  We also specify procedures for reporting pseudowire\
   status changes, for passing additional information about the\
   pseudowire as needed, and for releasing the bindings.\
\
\
\
\
\
Martini, et al.             Standards Track                     [Page 3]\
\
RFC 4447                     PWE3 Using LDP                   April 2006\
\
\
   In the protocol specified herein, the pseudowire demultiplexor field\
   is an MPLS label.  Thus, the packets that are transmitted from one\
   end of the pseudowire to the other are MPLS packets, which must be\
   transmitted through an MPLS tunnel.  However, if the pseudowire\
   endpoints are immediately adjacent and penultimate hop popping\
   behavior is in use, the MPLS tunnel may not be necessary.  Any sort\
   of PSN tunnel can be used, as long as it is possible to transmit MPLS\
   packets through it.  The PSN tunnel can itself be an MPLS LSP, or any\
   other sort of tunnel that can carry MPLS packets.  Procedures for\
   setting up and maintaining the MPLS tunnels are outside the scope of\
   this document.\
\
   This document deals only with the setup and maintenance of point-to-\
   point pseudowires.  Neither point-to-multipoint nor multipoint-to-\
   point pseudowires are discussed.\
\
   QoS-related issues are not discussed in this document.  The following\
   two figures describe the reference models that are derived from\
   [RFC3985] to support the PW emulated services.\
\
         |<-------------- Emulated Service ---------------->|\
         |                                                  |\
         |          |<------- Pseudowire ------->|          |\
         |          |                            |          |\
         |Attachment|    |<-- PSN Tunnel -->|    |Attachment|\
         |  Circuit V    V                  V    V  Circuit |\
         V   (AC)   +----+                  +----+   (AC)   V\
   +-----+    |     | PE1|==================| PE2|     |    +-----+\
   |     |----------|............PW1.............|----------|     |\
   | CE1 |    |     |    |                  |    |     |    | CE2 |\
   |     |----------|............PW2.............|----------|     |\
   +-----+  ^ |     |    |==================|    |     | ^  +-----+\
         ^  |       +----+                  +----+     | |  ^\
         |  |   Provider Edge 1         Provider Edge 2  |  |\
         |  |                                            |  |\
   Customer |                                            | Customer\
   Edge 1   |                                            | Edge 2\
            |                                            |\
      native service                               native service\
\
                     Figure 1: PWE3 Reference Model\
\
\
\
\
\
\
\
\
\
\
Martini, et al.             Standards Track                     [Page 4]\
\
RFC 4447                     PWE3 Using LDP                   April 2006\
\
\
   +-----------------+                           +-----------------+\
   |Emulated Service |                           |Emulated Service |\
   |(e.g., TDM, ATM) |<==== Emulated Service ===>|(e.g., TDM, ATM) |\
   +-----------------+                           +-----------------+\
   |    Payload      |                           |    Payload      |\
   |  Encapsulation  |<====== Pseudowire =======>|  Encapsulation  |\
   +-----------------+                           +-----------------+\
   |PW Demultiplexer |                           |PW Demultiplexer |\
   |   PSN Tunnel,   |<======= PSN Tunnel ======>|  PSN Tunnel,    |\
   | PSN & Physical  |                           | PSN & Physical  |\
   |     Layers      |                           |    Layers       |\
   +-------+---------+        __________         +---------+-------+\
           |                /            \\                 |\
           +===============/      PSN     \\================+\
                           \\              /\
                            \\____________/\
\
             Figure 2: PWE3 Protocol Stack Reference Model\
\
   For the purpose of this document, PE1 will be defined as the ingress\
   router, and PE2 as the egress router.  A layer 2 PDU will be received\
   at PE1, encapsulated at PE1, transported and decapsulated at PE2, and\
   transmitted out of PE2.\
\
2.  Specification of Requirements\
\
   The key words "MUST", "MUST NOT", "REQUIRED", "SHALL", "SHALL NOT",\
   "SHOULD", "SHOULD NOT", "RECOMMENDED", "MAY", and "OPTIONAL" in this\
   document are to be interpreted as described in [RFC2119].\
\
3.  The Pseudowire Label\
\
   Suppose that it is desired to transport Layer 2 PDUs from ingress LSR\
   PE1 to egress LSR PE2, across an intervening MPLS-enabled network.\
   We assume that there is an MPLS tunnel from PE1 to PE2.  That is, we\
   assume that PE1 can cause a packet to be delivered to PE2 by\
   encapsulating the packet in an "MPLS tunnel header" and sending the\
   result to one of its adjacencies.  The MPLS tunnel is an MPLS Label\
   Switched Path (LSP); thus, putting on an MPLS tunnel encapsulation is\
   a matter of pushing on an MPLS label.\
\
   We presuppose that a large number of pseudowires can be carried\
   through a single MPLS tunnel.  Thus, it is never necessary to\
   maintain state in the network core for individual pseudowires.  We do\
   not presuppose that the MPLS tunnels are point to point; although the\
   pseudowires are point to point, the MPLS tunnels may be multipoint to\
   point.  We do not presuppose that PE2 will even be able to determine\
   the MPLS tunnel through which a received packet was transmitted.\
\
\
\
Martini, et al.             Standards Track                     [Page 5]\
\
RFC 4447                     PWE3 Using LDP                   April 2006\
\
\
   (For example, if the MPLS tunnel is an LSP and penultimate hop\
   popping is used, when the packet arrives at PE2, it will contain no\
   information identifying the tunnel.)\
\
   When PE2 receives a packet over a pseudowire, it must be able to\
   determine that the packet was in fact received over a pseudowire, and\
   it must be able to associate that packet with a particular\
   pseudowire.  PE2 is able to do this by examining the MPLS label that\
   serves as the pseudowire demultiplexor field shown in Figure 2.  Call\
   this label the "PW label".\
\
   When PE1 sends a Layer 2 PDU to PE2, it creates an MPLS packet by\
   adding the PW label to the packet, thus creating the first entry of\
   the label stack.  If the PSN tunnel is an MPLS LSP, the PE1 pushes\
   another label (the tunnel label) onto the packet as the second entry\
   of the label stack.  The PW label is not visible again until the MPLS\
   packet reaches PE2.  PE2's disposition of the packet is based on the\
   PW label.\
\
   If the payload of the MPLS packet is, for example, an ATM AAL5 PDU,\
   the PW label will generally correspond to a particular ATM VC at PE2.\
   That is, PE2 needs to be able to infer from the PW label the outgoing\
   interface and the VPI/VCI value for the AAL5 PDU.  If the payload is\
   a Frame Relay PDU, then PE2 needs to be able to infer from the PW\
   label the outgoing interface and the DLCI value.  If the payload is\
   an Ethernet frame, then PE2 needs to be able to infer from the PW\
   label the outgoing interface, and perhaps the VLAN identifier.  This\
   process is uni-directional and will be repeated independently for\
   bi-directional operation.  It is REQUIRED that the same PW ID and PW\
   type be assigned for a given circuit in both directions.  The group\
   ID (see below) MUST NOT be required to match in both directions.  The\
   transported frame MAY be modified when it reaches the egress router.\
   If the header of the transported Layer 2 frame is modified, this MUST\
   be done at the egress LSR only.  Note that the PW label must always\
   be at the bottom of the packet's label stack, and labels MUST be\
   allocated from the per-platform label space.\
\
\
   This document does not specify a method for distributing the MPLS\
   tunnel label or any other labels that may appear above the PW label\
   on the stack.  Any acceptable method of MPLS label distribution will\
   do.  This document specifies a protocol for assigning and\
   distributing the PW label.  This protocol is LDP, extended as\
   specified in the remainder of this document.  An LDP session must be\
   set up between the pseudowire endpoints.  LDP MUST be used in its\
   "downstream unsolicited" mode.  LDP's "liberal label retention" mode\
   SHOULD be used.\
\
\
\
\
Martini, et al.             Standards Track                     [Page 6]\
\
RFC 4447                     PWE3 Using LDP                   April 2006\
\
\
   In addition to the protocol specified herein, static assignment of PW\
   labels may be used, and implementations of this protocol SHOULD\
   provide support for static assignment.\
\
   This document specifies all the procedures necessary to set up and\
   maintain the pseudowires needed to support "unswitched" point-to-\
   point services, where each endpoint of the pseudowire is provisioned\
   with the identify of the other endpoint.  There are also protocol\
   mechanisms specified herein that can be used to support switched\
   services and other provisioning models.  However, the use of the\
   protocol mechanisms to support those other models and services is not\
   described in this document.\
\
4.  Details Specific to Particular Emulated Services\
\
4.1.  IP Layer 2 Transport\
\
   This mode carries IP packets over a pseudowire.  The encapsulation\
   used is according to [RFC3032].  The PW control word MAY be inserted\
   between the MPLS label stack and the IP payload.  The encapsulation\
   of the IP packets for forwarding on the attachment circuit is\
   implementation specific, is part of the native service processing\
   (NSP) function [RFC3985], and is outside the scope of this document.\
\
5.  LDP\
\
   The PW label bindings are distributed using the LDP downstream\
   unsolicited mode described in [RFC3036].  The PEs will establish an\
   LDP session using the Extended Discovery mechanism described in [LDP,\
   sections 2.4.2 and 2.5].\
\
   An LDP Label Mapping message contains an FEC TLV, a Label TLV, and\
   zero or more optional parameter TLVs.\
\
   The FEC TLV is used to indicate the meaning of the label.  In the\
   current context, the FEC TLV would be used to identify the particular\
   pseudowire that a particular label is bound to.  In this\
   specification, we define two new FEC TLVs to be used for identifying\
   pseudowires.  When setting up a particular pseudowire, only one of\
   these FEC TLVs is used.  The one to be used will depend on the\
   particular service being emulated and on the particular provisioning\
   model being supported.\
\
   LDP allows each FEC TLV to consist of a set of FEC elements.  For\
   setting up and maintaining pseudowires, however, each FEC TLV MUST\
   contain exactly one FEC element.\
\
\
\
\
\
Martini, et al.             Standards Track                     [Page 7]\
\
RFC 4447                     PWE3 Using LDP                   April 2006\
\
\
   The LDP base specification has several kinds of label TLVs, including\
   the Generic Label TLV, as specified in [RFC3036], section 3.4.2.1.\
   For setting up and maintaining pseudowires, the Generic Label TLV\
   MUST be used.\
\
5.1.  LDP Extensions\
\
   This document specifies no new LDP messages.\
\
   This document specifies the following new TLVs to be used with LDP:\
\
   TLV                    Specified in Section     Defined for Message\
   ===================================================================\
   PW Status TLV                  5.4.2            Notification\
   PW Interface Parameters TLV    5.3.2.1          FEC\
   PW Grouping  ID TLV            5.3.2.2          FEC\
\
\
   Additionally, the following new FEC element types are defined:\
\
   FEC Element Type        Specified in Section    Defined for Message\
   ===================================================================\
   0x80                            5.2             FEC\
   0x81                            5.3             FEC\
\
   The following new LDP error codes are also defined:\
\
   Status Code                                     Specified in Section\
   ====================================================================\
   "Illegal C-Bit"                                         6.1\
   "Wrong C-Bit"                                           6.2\
   "Incompatible bit-rate"                                [CEP]\
   "CEP/TDM mis-configuration"                            [CEP]\
   "PW status"                                            5.4.2\
   "Unassigned/Unrecognized TAI"                          5.3.3\
   "Generic Misconfiguration Error"                      [SAToP]\
   "Label Withdraw PW Status Method Not Supported"        5.4.1\
\
5.2.  The PWid FEC Element\
\
   The PWid FEC element may be used whenever both pseudowire endpoints\
   have been provisioned with the same 32-bit identifier for the\
   pseudowire.\
\
\
\
\
\
\
\
\
Martini, et al.             Standards Track                     [Page 8]\
\
RFC 4447                     PWE3 Using LDP                   April 2006\
\
\
   For this purpose, a new type of FEC element is defined.  The FEC\
   element type is 0x80 and is defined as follows:\
\
    0                   1                   2                   3\
    0 1 2 3 4 5 6 7 8 9 0 1 2 3 4 5 6 7 8 9 0 1 2 3 4 5 6 7 8 9 0 1\
   +-+-+-+-+-+-+-+-+-+-+-+-+-+-+-+-+-+-+-+-+-+-+-+-+-+-+-+-+-+-+-+-+\
   |  PWid (0x80)  |C|         PW type             |PW info Length |\
   +-+-+-+-+-+-+-+-+-+-+-+-+-+-+-+-+-+-+-+-+-+-+-+-+-+-+-+-+-+-+-+-+\
   |                          Group ID                             |\
   +-+-+-+-+-+-+-+-+-+-+-+-+-+-+-+-+-+-+-+-+-+-+-+-+-+-+-+-+-+-+-+-+\
   |                           PW ID                               |\
   +-+-+-+-+-+-+-+-+-+-+-+-+-+-+-+-+-+-+-+-+-+-+-+-+-+-+-+-+-+-+-+-+\
   |                Interface Parameter  Sub-TLV                   |\
   |                              "                                |\
   |                              "                                |\
   +-+-+-+-+-+-+-+-+-+-+-+-+-+-+-+-+-+-+-+-+-+-+-+-+-+-+-+-+-+-+-+-+\
\
   -  PW type\
\
      A 15-bit quantity containing a value that represents the type of\
      PW.  Assigned values are specified in "IANA Allocations for\
      Pseudowire Edge to Edge Emulation (PWE3)" [IANA].\
\
   -  Control word bit (C)\
\
      The bit (C) is used to flag the presence of a control word as\
      follows:\
\
         C = 1  Control word present on this PW.\
         C = 0  No control word present on this PW.\
\
      Please see the section "C-Bit Handling Procedures" for further\
      explanation.\
\
   -  PW information length\
\
      Length of the PW ID field and the interface parameters sub-TLV in\
      octets.  If this value is 0, then it references all PWs using the\
      specified group ID, and there is no PW ID present; nor are there\
      any interface parameter sub-TLVs.\
\
   -  Group ID\
\
      An arbitrary 32-bit value that represents a group of PWs that is\
      used to create groups in the PW space.  The group ID is intended\
      to be used as a port index, or a virtual tunnel index.  To\
      simplify configuration, a particular PW ID at ingress could be\
      part of the virtual tunnel for transport to the egress router.\
\
\
\
Martini, et al.             Standards Track                     [Page 9]\
\
RFC 4447                     PWE3 Using LDP                   April 2006\
\
\
      The Group ID is very useful for sending wild card label\
      withdrawals, or PW wild card status notification messages to\
      remote PEs upon physical port failure.\
\
   -  PW ID\
\
      A non-zero 32-bit connection ID that, together with the PW type,\
      identifies a particular PW.  Note that the PW ID and the PW type\
      MUST be the same at both endpoints.\
\
   -  Interface Parameter Sub-TLV\
\
      This variable-length TLV is used to provide interface-specific\
      parameters, such as attachment circuit MTU.\
\
      Note that as the "interface parameter sub-TLV" is part of the FEC,\
      the rules of LDP make it impossible to change the interface\
      parameters once the pseudowire has been set up.  Thus, the\
      interface parameters field must not be used to pass information,\
      such as status information, that may change during the life of the\
      pseudowire.  Optional parameter TLVs should be used for that\
      purpose.\
\
   Using the PWid FEC, each of the two pseudowire endpoints\
   independently initiates the setup of a unidirectional LSP.  An\
   outgoing LSP and an incoming LSP are bound together into a single\
   pseudowire if they have the same PW ID and PW type.\
\
5.3.  The Generalized PWid FEC Element\
\
   The PWid FEC element can be used if a unique 32-bit value has been\
   assigned to the PW, and if each endpoint has been provisioned with\
   that value.  The Generalized PWid FEC element requires that the PW\
   endpoints be uniquely identified; the PW itself is identified as a\
   pair of endpoints.  In addition, the endpoint identifiers are\
   structured to support applications where the identity of the remote\
   endpoints needs to be auto-discovered rather than statically\
   configured.\
\
   The "Generalized PWid FEC Element" is FEC type 0x81.\
\
   The Generalized PWid FEC Element does not contain anything\
   corresponding to the "Group ID" of the PWid FEC element.  The\
   functionality of the "Group ID" is provided by a separate optional\
   LDP TLV, the "PW Grouping TLV", described below.  The Interface\
   Parameters field of the PWid FEC element is also absent; its\
   functionality is replaced by the optional Interface Parameters TLV,\
   described below.\
\
\
\
Martini, et al.             Standards Track                    [Page 10]\
\
RFC 4447                     PWE3 Using LDP                   April 2006\
\
\
5.3.1.  Attachment Identifiers\
\
   As discussed in [RFC3985], a pseudowire can be thought of as\
   connecting two "forwarders".  The protocol used to set up a\
   pseudowire must allow the forwarder at one end of a pseudowire to\
   identify the forwarder at the other end.  We use the term "attachment\
   identifier", or "AI", to refer to the field that the protocol uses to\
   identify the forwarders.  In the PWid FEC, the PWid field serves as\
   the AI.  In this section, we specify a more general form of AI that\
   is structured and of variable length.\
\
   Every Forwarder in a PE must be associated with an Attachment\
   Identifier (AI), either through configuration or through some\
   algorithm.  The Attachment Identifier must be unique in the context\
   of the PE router in which the Forwarder resides.  The combination\
   <PE router IP address, AI> must be globally unique.\
\
   It is frequently convenient to regard a set of Forwarders as being\
   members of a particular "group", where PWs may only be set up among\
   members of a group.  In such cases, it is convenient to identify the\
   Forwarders relative to the group, so that an Attachment Identifier\
   would consist of an Attachment Group Identifier (AGI) plus an\
   Attachment Individual Identifier (AII).\
\
   An Attachment Group Identifier may be thought of as a VPN-id, or a\
   VLAN identifier, some attribute that is shared by all the Attachment\
   PWs (or pools thereof) that are allowed to be connected.\
\
   The details of how to construct the AGI and AII fields identifying\
   the pseudowire endpoints are outside the scope of this specification.\
   Different pseudowire applications, and different provisioning models,\
   will require different sorts of AGI and AII fields.  The\
   specification of each such application and/or model must include the\
   rules for constructing the AGI and AII fields.\
\
   As previously discussed, a (bidirectional) pseudowire consists of a\
   pair of unidirectional LSPs, one in each direction.  If a particular\
   pseudowire connects PE1 with PE2, the PW direction from PE1 to PE2\
   can be identified as:\
\
      <PE1, <AGI, AII1>, PE2, <AGI, AII2>>,\
\
   The PW direction from PE2 to PE1 can be identified by:\
\
      <PE2, <AGI, AII2>, PE1, <AGI, AII1>>.\
\
\
\
\
\
\
Martini, et al.             Standards Track                    [Page 11]\
\
RFC 4447                     PWE3 Using LDP                   April 2006\
\
\
   Note that the AGI must be the same at both endpoints, but the AII\
   will in general be different at each endpoint.  Thus, from the\
   perspective of a particular PE, each pseudowire has a local or\
   "Source AII", and a remote or "Target AII".  The pseudowire setup\
   protocol can carry all three of these quantities:\
\
      -  Attachment Group Identifier (AGI)\
\
      -  Source Attachment Individual Identifier (SAII)\
\
      -  Target Attachment Individual Identifier (TAII)\
\
   If the AGI is non-null, then the Source AI (SAI) consists of the AGI\
   together with the SAII, and the Target AI (TAI) consists of the TAII\
   together with the AGI.  If the AGI is null, then the SAII and TAII\
   are the SAI and TAI, respectively.\
\
   The interpretation of the SAI and TAI is a local matter at the\
   respective endpoint.\
\
   The association of two unidirectional LSPs into a single\
   bidirectional pseudowire depends on the SAI and the TAI.  Each\
   application and/or provisioning model that uses the Generalized ID\
   FEC element must specify the rules for performing this association.\
\
\
\
\
\
\
\
\
\
\
\
\
\
\
\
\
\
\
\
\
\
\
\
\
\
\
\
Martini, et al.             Standards Track                    [Page 12]\
\
RFC 4447                     PWE3 Using LDP                   April 2006\
\
\
5.3.2.  Encoding the Generalized ID FEC Element\
\
   FEC element type 0x81 is used.  The FEC element is encoded as\
   follows:\
\
    0                   1                   2                   3\
    0 1 2 3 4 5 6 7 8 9 0 1 2 3 4 5 6 7 8 9 0 1 2 3 4 5 6 7 8 9 0 1\
   +-+-+-+-+-+-+-+-+-+-+-+-+-+-+-+-+-+-+-+-+-+-+-+-+-+-+-+-+-+-+-+-+\
   |Gen PWid (0x81)|C|         PW Type             |PW info Length |\
   +-+-+-+-+-+-+-+-+-+-+-+-+-+-+-+-+-+-+-+-+-+-+-+-+-+-+-+-+-+-+-+-+\
   |   AGI Type    |    Length     |      Value                    |\
   +-+-+-+-+-+-+-+-+-+-+-+-+-+-+-+-+-+-+-+-+-+-+-+-+-+-+-+-+-+-+-+-+\
   ~                    AGI  Value (contd.)                        ~\
   |                                                               |\
   +-+-+-+-+-+-+-+-+-+-+-+-+-+-+-+-+-+-+-+-+-+-+-+-+-+-+-+-+-+-+-+-+\
   |   AII Type    |    Length     |      Value                    |\
   +-+-+-+-+-+-+-+-+-+-+-+-+-+-+-+-+-+-+-+-+-+-+-+-+-+-+-+-+-+-+-+-+\
   ~                   SAII  Value (contd.)                        ~\
   |                                                               |\
   +-+-+-+-+-+-+-+-+-+-+-+-+-+-+-+-+-+-+-+-+-+-+-+-+-+-+-+-+-+-+-+-+\
   |   AII Type    |    Length     |      Value                    |\
   +-+-+-+-+-+-+-+-+-+-+-+-+-+-+-+-+-+-+-+-+-+-+-+-+-+-+-+-+-+-+-+-+\
   ~                   TAII Value (contd.)                         ~\
   |                                                               |\
   +-+-+-+-+-+-+-+-+-+-+-+-+-+-+-+-+-+-+-+-+-+-+-+-+-+-+-+-+-+-+-+-+\
\
   This document does not specify the AII and AGI type field values;\
   specification of the type field values to be used for a particular\
   application is part of the specification of that application.  IANA\
   has assigned these values using the method defined in the [IANA]\
   document.\
\
   The SAII, TAII, and AGI are simply carried as octet strings.  The\
   length byte specifies the size of the Value field.  The null string\
   can be sent by setting the length byte to 0.  If a particular\
   application does not need all three of these sub-elements, it MUST\
   send all the sub-elements but set the length to 0 for the unused\
   sub-elements.\
\
   The PW information length field contains the length of the SAII,\
   TAII, and AGI, combined in octets.  If this value is 0, then it\
   references all PWs using the specified grouping ID.  In this case,\
   there are no other FEC element fields (AGI, SAII, etc.) present, nor\
   any interface parameters TLVs.\
\
   Note that the interpretation of a particular field as AGI, SAII, or\
   TAII depends on the order of its occurrence.  The type field\
   identifies the type of the AGI, SAII, or TAII.  When comparing two\
\
\
\
Martini, et al.             Standards Track                    [Page 13]\
\
RFC 4447                     PWE3 Using LDP                   April 2006\
\
\
   occurrences of an AGI (or SAII or TAII), the two occurrences are\
   considered identical if the type, length, and value fields of one are\
   identical, respectively, to those of the other.\
\
5.3.2.1.  Interface Parameters TLV\
\
   This TLV MUST only be used when sending the Generalized PW FEC.  It\
   specifies interface-specific parameters.  Specific parameters, when\
   applicable, MUST be used to validate that the PEs and the ingress and\
   egress ports at the edges of the circuit have the necessary\
   capabilities to interoperate with each other.\
\
    0                   1                   2                   3\
    0 1 2 3 4 5 6 7 8 9 0 1 2 3 4 5 6 7 8 9 0 1 2 3 4 5 6 7 8 9 0 1\
   +-+-+-+-+-+-+-+-+-+-+-+-+-+-+-+-+-+-+-+-+-+-+-+-+-+-+-+-+-+-+-+-+\
   |0|0|  PW Intf P. TLV (0x096B)  |            Length             |\
   +-+-+-+-+-+-+-+-+-+-+-+-+-+-+-+-+-+-+-+-+-+-+-+-+-+-+-+-+-+-+-+-+\
   | Sub-TLV Type  |    Length     |    Variable Length Value      |\
   +-+-+-+-+-+-+-+-+-+-+-+-+-+-+-+-+-+-+-+-+-+-+-+-+-+-+-+-+-+-+-+-+\
   |                         Variable Length Value                 |\
   |                             "                                 |\
   +-+-+-+-+-+-+-+-+-+-+-+-+-+-+-+-+-+-+-+-+-+-+-+-+-+-+-+-+-+-+-+-+\
\
   A more detailed description of this field can be found in the section\
   "Interface Parameters Sub-TLV", below.\
\
5.3.2.2.  PW Grouping TLV\
\
    0                   1                   2                   3\
    0 1 2 3 4 5 6 7 8 9 0 1 2 3 4 5 6 7 8 9 0 1 2 3 4 5 6 7 8 9 0 1\
   +-+-+-+-+-+-+-+-+-+-+-+-+-+-+-+-+-+-+-+-+-+-+-+-+-+-+-+-+-+-+-+-+\
   |0|0|PW Grouping ID TLV (0x096C)|            Length             |\
   +-+-+-+-+-+-+-+-+-+-+-+-+-+-+-+-+-+-+-+-+-+-+-+-+-+-+-+-+-+-+-+-+\
   |                             Value                             |\
   +-+-+-+-+-+-+-+-+-+-+-+-+-+-+-+-+-+-+-+-+-+-+-+-+-+-+-+-+-+-+-+-+\
\
   The PW Grouping ID is an arbitrary 32-bit value that represents an\
   arbitrary group of PWs.  It is used to create group PWs; for example,\
   a PW Grouping ID can be used as a port index and assigned to all PWs\
   that lead to that port.  Use of the PW Grouping ID enables one to\
   send "wild card" label withdrawals, or "wild card" status\
   notification messages, to remote PEs upon physical port failure.\
\
   Note Well: The PW Grouping ID is different from, and has no relation\
   to, the Attachment Group Identifier.\
\
   The PW Grouping ID TLV is not part of the FEC and will not be\
   advertised except in the PW FEC advertisement.  The advertising PE\
\
\
\
Martini, et al.             Standards Track                    [Page 14]\
\
RFC 4447                     PWE3 Using LDP                   April 2006\
\
\
   MAY use the wild card withdraw semantics, but the remote PEs MUST\
   implement support for wild card messages.  This TLV MUST only be used\
   when sending the Generalized PW ID FEC.\
\
   To issue a wildcard command (status or withdraw):\
\
   -  Set the PW Info Length to 0 in the Generalized ID FEC Element.\
\
   -  Send only the PW Grouping ID TLV with the FEC (no AGI/SAII/TAII is\
      sent).\
\
5.3.3.  Signaling Procedures\
\
   In order for PE1 to begin signaling PE2, PE1 must know the address of\
   the remote PE2, and a TAI.  This information may have been configured\
   at PE1, or it may have been learned dynamically via some\
   autodiscovery procedure.\
\
   The egress PE (PE1), which has knowledge of the ingress PE, initiates\
   the setup by sending a Label Mapping Message to the ingress PE (PE2).\
   The Label Mapping message contains the FEC TLV, carrying the\
   Generalized PWid FEC Element (type 0x81).  The Generalized PWid FEC\
   element contains the AGI, SAII, and TAII information.\
\
   Next, when PE2 receives such a Label Mapping message, PE2 interprets\
   the message as a request to set up a PW whose endpoint (at PE2) is\
   the Forwarder identified by the TAI.  From the perspective of the\
   signaling protocol, exactly how PE2 maps AIs to Forwarders is a local\
   matter.  In some Virtual Private Wire Services (VPWS) provisioning\
   models, the TAI might, for example, be a string that identifies a\
   particular Attachment Circuit, such as "ATM3VPI4VCI5", or it might,\
   for example, be a string, such as "Fred", that is associated by\
   configuration with a particular Attachment Circuit.  In VPLS, the AGI\
   could be a VPN-id, identifying a particular VPLS instance.\
\
   If PE2 cannot map the TAI to one of its Forwarders, then PE2 sends a\
   Label Release message to PE1, with a Status Code of\
   "Unassigned/Unrecognized TAI", and the processing of the Label\
   Mapping message is complete.\
\
   The FEC TLV sent in a Label Release message is the same as the FEC\
   TLV received in the Label Mapping being released (but without the\
   interface parameter TLV).  More generally, the FEC TLV is the same in\
   all LDP messages relating to the same PW.  In a Label Release, this\
   means that the SAII is the remote peer's AII and the TAII is the\
   sender's local AII.\
\
\
\
\
\
Martini, et al.             Standards Track                    [Page 15]\
\
RFC 4447                     PWE3 Using LDP                   April 2006\
\
\
   If the Label Mapping Message has a valid TAI, PE2 must decide whether\
   to accept it.  The procedures for so deciding will depend on the\
   particular type of Forwarder identified by the TAI.  Of course, the\
   Label Mapping message may be rejected due to standard LDP error\
   conditions as detailed in [RFC3036].\
\
   If PE2 decides to accept the Label Mapping message, then it has to\
   make sure that a PW LSP is set up in the opposite (PE1-->PE2)\
   direction.  If it has already signaled for the corresponding PW LSP\
   in that direction, nothing more needs to be done.  Otherwise, it must\
   initiate such signaling by sending a Label Mapping message to PE1.\
   This is very similar to the Label Mapping message PE2 received, but\
   the SAI and TAI are reversed.\
\
   Thus, a bidirectional PW consists of two LSPs, where the FEC of one\
   has the SAII and TAII reversed with respect to the FEC of the other.\
\
5.4.  Signaling of Pseudowire Status\
\
5.4.1.  Use of Label Mappings Messages\
\
   The PEs MUST send Label Mapping Messages to their peers as soon as\
   the PW is configured and administratively enabled, regardless of the\
   attachment circuit state.  The PW label should not be withdrawn\
   unless the operator administratively configures the pseudowire down\
   (or the PW configuration is deleted entirely).  Using the procedures\
   outlined in this section, a simple label withdraw method MAY also be\
   supported as a legacy means of signaling PW status and AC status.  In\
   any case, if the label-to-PW binding is not available, the PW MUST be\
   considered in the down state.\
\
   Once the PW status negotiation procedures are completed, if they\
   result in the use of the label withdraw method for PW status\
   communication, and this method is not supported by one of the PEs,\
   then that PE must send a Label Release Message to its peer with the\
   following error:\
\
   "Label Withdraw PW Status Method Not Supported"\
\
   If the label withdraw method for PW status communication is selected\
   for the PW, it will result in the Label Mapping Message being\
   advertised only if the attachment circuit is active.  The PW status\
   signaling procedures described in this section MUST be fully\
   implemented.\
\
\
\
\
\
\
\
Martini, et al.             Standards Track                    [Page 16]\
\
RFC 4447                     PWE3 Using LDP                   April 2006\
\
\
5.4.2.  Signaling PW Status\
\
   The PE devices use an LDP TLV to indicate status to their remote\
   peers.  This PW Status TLV contains more information than the\
   alternative simple Label Withdraw message.\
\
   The format of the PW Status TLV is:\
\
    0                   1                   2                   3\
    0 1 2 3 4 5 6 7 8 9 0 1 2 3 4 5 6 7 8 9 0 1 2 3 4 5 6 7 8 9 0 1\
   +-+-+-+-+-+-+-+-+-+-+-+-+-+-+-+-+-+-+-+-+-+-+-+-+-+-+-+-+-+-+-+-+\
   |1|0|     PW Status (0x096A)    |            Length             |\
   +-+-+-+-+-+-+-+-+-+-+-+-+-+-+-+-+-+-+-+-+-+-+-+-+-+-+-+-+-+-+-+-+\
   |                         Status Code                           |\
   +-+-+-+-+-+-+-+-+-+-+-+-+-+-+-+-+-+-+-+-+-+-+-+-+-+-+-+-+-+-+-+-+\
\
   The status code is a 4-octet bit field as specified in the PW IANA\
   Allocations document [IANA].  The length specifies the length of the\
   Status Code field in octets (equal to 4).\
\
   Each bit in the status code field can be set individually to indicate\
   more than a single failure at once.  Each fault can be cleared by\
   sending an appropriate Notification message in which the respective\
   bit is cleared.  The presence of the lowest bit (PW Not Forwarding)\
   acts only as a generic failure indication when there is a link-down\
   event for which none of the other bits apply.\
\
   The Status TLV is transported to the remote PW peer via the LDP\
   Notification message.  The general format of the Notification Message\
   is:\
\
    0                   1                   2                   3\
    0 1 2 3 4 5 6 7 8 9 0 1 2 3 4 5 6 7 8 9 0 1 2 3 4 5 6 7 8 9 0 1\
   +-+-+-+-+-+-+-+-+-+-+-+-+-+-+-+-+-+-+-+-+-+-+-+-+-+-+-+-+-+-+-+-+\
   |0|   Notification (0x0001)     |      Message Length           |\
   +-+-+-+-+-+-+-+-+-+-+-+-+-+-+-+-+-+-+-+-+-+-+-+-+-+-+-+-+-+-+-+-+\
   |                       Message ID                              |\
   +-+-+-+-+-+-+-+-+-+-+-+-+-+-+-+-+-+-+-+-+-+-+-+-+-+-+-+-+-+-+-+-+\
   |                       Status (TLV)                            |\
   +-+-+-+-+-+-+-+-+-+-+-+-+-+-+-+-+-+-+-+-+-+-+-+-+-+-+-+-+-+-+-+-+\
   |                      PW Status TLV                            |\
   +-+-+-+-+-+-+-+-+-+-+-+-+-+-+-+-+-+-+-+-+-+-+-+-+-+-+-+-+-+-+-+-+\
   |           PWId FEC TLV or Generalized ID FEC TLV              |\
   +-+-+-+-+-+-+-+-+-+-+-+-+-+-+-+-+-+-+-+-+-+-+-+-+-+-+-+-+-+-+-+-+\
\
\
\
\
\
\
\
Martini, et al.             Standards Track                    [Page 17]\
\
RFC 4447                     PWE3 Using LDP                   April 2006\
\
\
   The Status TLV status code is set to 0x00000028, "PW status", to\
   indicate that PW status follows.  Since this notification does not\
   refer to any particular message, the Message Id and Message Type\
   fields are set to 0.\
\
   The PW FEC TLV SHOULD not include the interface parameter sub-TLVs,\
   as they are ignored in the context of this message.  When a PE's\
   attachment circuit encounters an error, use of the PW Notification\
   Message allows the PE to send a single "wild card" status message,\
   using a PW FEC TLV with only the group ID set, to denote this change\
   in status for all affected PW connections.  This status message\
   contains either the PW FEC TLV with only the group ID set, or else it\
   contains the Generalized FEC TLV with only the PW Grouping ID TLV.\
\
   As mentioned above, the Group ID field of the PWid FEC element, or\
   the PW Grouping ID TLV used with the Generalized ID FEC element, can\
   be used to send a status notification for all arbitrary sets of PWs.\
   This procedure is OPTIONAL, and if it is implemented, the LDP\
   Notification message should be as follows: If the PWid FEC element is\
   used, the PW information length field is set to 0, the PW ID field is\
   not present, and the interface parameter sub-TLVs are not present.\
   If the Generalized FEC element is used, the AGI, SAII, and TAII are\
   not present, the PW information length field is set to 0, the PW\
   Grouping ID TLV is included, and the Interface Parameters TLV is\
   omitted.  For the purpose of this document, this is called the "wild\
   card PW status notification procedure", and all PEs implementing this\
   design are REQUIRED to accept such a notification message but are not\
   required to send it.\
\
5.4.3.  Pseudowire Status Negotiation Procedures\
\
   When a PW is first set up, the PEs MUST attempt to negotiate the\
   usage of the PW status TLV.  This is accomplished as follows: A PE\
   that supports the PW Status TLV MUST include it in the initial Label\
   Mapping message following the PW FEC and the interface parameter\
   sub-TLVs.  The PW Status TLV will then be used for the lifetime of\
   the pseudowire.  This is shown in the following diagram:\
\
\
\
\
\
\
\
\
\
\
\
\
\
\
Martini, et al.             Standards Track                    [Page 18]\
\
RFC 4447                     PWE3 Using LDP                   April 2006\
\
\
    0                   1                   2                   3\
    0 1 2 3 4 5 6 7 8 9 0 1 2 3 4 5 6 7 8 9 0 1 2 3 4 5 6 7 8 9 0 1\
   +-+-+-+-+-+-+-+-+-+-+-+-+-+-+-+-+-+-+-+-+-+-+-+-+-+-+-+-+-+-+-+-+\
   |                                                               |\
   +                 PWId FEC or Generalized ID FEC                +\
   |                                                               |\
   +-+-+-+-+-+-+-+-+-+-+-+-+-+-+-+-+-+-+-+-+-+-+-+-+-+-+-+-+-+-+-+-+\
   |                       Interface Parameters                    |\
   |                              "                                |\
   |                              "                                |\
   +-+-+-+-+-+-+-+-+-+-+-+-+-+-+-+-+-+-+-+-+-+-+-+-+-+-+-+-+-+-+-+-+\
   |0|0| Generic Label (0x0200)    |      Length                   |\
   +-+-+-+-+-+-+-+-+-+-+-+-+-+-+-+-+-+-+-+-+-+-+-+-+-+-+-+-+-+-+-+-+\
   |     Label                                                     |\
   +-+-+-+-+-+-+-+-+-+-+-+-+-+-+-+-+-+-+-+-+-+-+-+-+-+-+-+-+-+-+-+-+\
   |1|0|     PW Status (0x096A)    |            Length             |\
   +-+-+-+-+-+-+-+-+-+-+-+-+-+-+-+-+-+-+-+-+-+-+-+-+-+-+-+-+-+-+-+-+\
   |                         Status Code                           |\
   +-+-+-+-+-+-+-+-+-+-+-+-+-+-+-+-+-+-+-+-+-+-+-+-+-+-+-+-+-+-+-+-+\
\
   If a PW Status TLV is included in the initial Label Mapping message\
   for a PW, then if the Label Mapping message from the remote PE for\
   that PW does not include a PW status TLV, or if the remote PE does\
   not support the PW Status TLV, the PW will revert to the label\
   withdraw method of signaling PW status.  Note that if the PW Status\
   TLV is not supported by the remote peer, the peer will automatically\
   ignore it, since the I (ignore) bit is set in the TLV.  The PW Status\
   TLV, therefore, will not be present in the corresponding FEC\
   advertisement from the remote LDP peer, which results in exactly the\
   above behavior.\
\
   If the PW Status TLV is not present following the FEC TLV in the\
   initial PW Label Mapping message received by a PE, then the PW Status\
   TLV will not be used, and both PEs supporting the pseudowire will\
   revert to the label withdraw procedure for signaling status changes.\
\
   If the negotiation process results in the usage of the PW status TLV,\
   then the actual PW status is determined by the PW status TLV that was\
   sent within the initial PW Label Mapping message.  Subsequent updates\
   of PW status are conveyed through the notification message.\
\
5.5.  Interface Parameters Sub-TLV\
\
   This field specifies interface-specific parameters.  When applicable,\
   it MUST be used to validate that the PEs and the ingress and egress\
   ports at the edges of the circuit have the necessary capabilities to\
   interoperate with each other.  The field structure is defined as\
   follows:\
\
\
\
Martini, et al.             Standards Track                    [Page 19]\
\
RFC 4447                     PWE3 Using LDP                   April 2006\
\
\
    0                   1                   2                   3\
    0 1 2 3 4 5 6 7 8 9 0 1 2 3 4 5 6 7 8 9 0 1 2 3 4 5 6 7 8 9 0 1\
   +-+-+-+-+-+-+-+-+-+-+-+-+-+-+-+-+-+-+-+-+-+-+-+-+-+-+-+-+-+-+-+-+\
   | Sub-TLV Type  |    Length     |    Variable Length Value      |\
   +-+-+-+-+-+-+-+-+-+-+-+-+-+-+-+-+-+-+-+-+-+-+-+-+-+-+-+-+-+-+-+-+\
   |                         Variable Length Value                 |\
   |                             "                                 |\
   +-+-+-+-+-+-+-+-+-+-+-+-+-+-+-+-+-+-+-+-+-+-+-+-+-+-+-+-+-+-+-+-+\
\
   The interface parameter sub-TLV type values are specified in "IANA\
   Allocations for Pseudowire Edge to Edge Emulation (PWE3)" [IANA].\
\
   The Length field is defined as the length of the interface parameter\
   including the parameter id and length field itself.  Processing of\
   the interface parameters should continue when unknown interface\
   parameters are encountered, and they MUST be silently ignored.\
\
   -  Interface MTU sub-TLV type\
\
      A 2-octet value indicating the MTU in octets.  This is the Maximum\
      Transmission Unit, excluding encapsulation overhead, of the egress\
      packet interface that will be transmitting the decapsulated PDU\
      that is received from the MPLS-enabled network.  This parameter is\
      applicable only to PWs transporting packets and is REQUIRED for\
      these PW types.  If this parameter does not match in both\
      directions of a specific PW, that PW MUST NOT be enabled.\
\
   -  Optional Interface Description string sub-TLV type\
\
      This arbitrary, and OPTIONAL, interface description string is used\
      to send a human-readable administrative string describing the\
      interface to the remote.  This parameter is OPTIONAL and is\
      applicable to all PW types.  The interface description parameter\
      string length is variable and can be from 0 to 80 octets.  Human-\
      readable text MUST be provided in the UTF-8 charset using the\
      Default Language [RFC2277].\
\
6.  Control Word\
\
6.1.  PW Types for Which the Control Word is REQUIRED\
\
   The Label Mapping messages that are sent in order to set up these PWs\
   MUST have c=1.  When a Label Mapping message for a PW of one of these\
   types is received and c=0, a Label Release message MUST be sent, with\
   an "Illegal C-bit" status code.  In this case, the PW will not be\
   enabled.\
\
\
\
\
\
Martini, et al.             Standards Track                    [Page 20]\
\
RFC 4447                     PWE3 Using LDP                   April 2006\
\
\
6.2.  PW Types for Which the Control Word is NOT Mandatory\
\
   If a system is capable of sending and receiving the control word on\
   PW types for which the control word is not mandatory, then each such\
   PW endpoint MUST be configurable with a parameter that specifies\
   whether the use of the control word is PREFERRED or NOT PREFERRED.\
   For each PW, there MUST be a default value of this parameter.  This\
   specification does NOT state what the default value should be.\
\
   If a system is NOT capable of sending and receiving the control word\
   on PW types for which the control word is not mandatory, then it\
   behaves exactly as if it were configured for the use of the control\
   word to be NOT PREFERRED.\
\
   If a Label Mapping message for the PW has already been received but\
   no Label Mapping message for the PW has yet been sent, then the\
   procedure is as follows:\
\
        -i. If the received Label Mapping message has c=0, send a Label\
            Mapping message with c=0; the control word is not used.\
\
       -ii. If the received Label Mapping message has c=1 and the PW is\
            locally configured such that the use of the control word is\
            preferred, then send a Label Mapping message with c=1; the\
            control word is used.\
\
      -iii. If the received Label Mapping message has c=1 and the PW is\
            locally configured such that the use of the control word is\
            not preferred or the control word is not supported, then act\
            as if no Label Mapping message for the PW had been received\
            (i.e., proceed to the next paragraph).\
\
   If a Label Mapping message for the PW has not already been received\
   (or if the received Label Mapping message had c=1 and either local\
   configuration says that the use of the control word is not preferred\
   or the control word is not supported), then send a Label Mapping\
   message in which the c bit is set to correspond to the locally\
   configured preference for use of the control word.  (That is, set c=1\
   if locally configured to prefer the control word, and set c=0 if\
   locally configured to prefer not to use the control word or if the\
   control word is not supported).\
\
\
\
\
\
\
\
\
\
\
Martini, et al.             Standards Track                    [Page 21]\
\
RFC 4447                     PWE3 Using LDP                   April 2006\
\
\
   The next action depends on what control message is next received for\
   that PW.  The possibilities are as follows:\
\
        -i. A Label Mapping message with the same c bit value as\
            specified in the Label Mapping message that was sent.  PW\
            setup is now complete, and the control word is used if c=1\
            but is not used if c=0.\
\
       -ii. A Label Mapping message with c=1, but the Label Mapping\
            message that was sent has c=0.  In this case, ignore the\
            received Label Mapping message and continue to wait for the\
            next control message for the PW.\
\
      -iii. A Label Mapping message with c=0, but the Label Mapping\
            message that was sent has c=1.  In this case, send a Label\
            Withdraw message with a "Wrong C-bit" status code, followed\
            by a Label Mapping message that has c=0.  PW setup is now\
            complete, and the control word is not used.\
\
       -iv. A Label Withdraw message with the "Wrong c-bit" status code.\
            Treat as a normal Label Withdraw, but do not respond.\
            Continue to wait for the next control message for the PW.\
\
   If at any time after a Label Mapping message has been received a\
   corresponding Label Withdraw or Release is received, the action taken\
   is the same as for any Label Withdraw or Release that might be\
   received at any time.\
\
   If both endpoints prefer the use of the control word, this procedure\
   will cause it to be used.  If either endpoint prefers not to use the\
   control word or does not support the control word, this procedure\
   will cause it not to be used.  If one endpoint prefers to use the\
   control word but the other does not, the one that prefers not to use\
   it is has no extra protocol to execute; it just waits for a Label\
   Mapping message that has c=0.\
\
   The diagram in Appendix A illustrates the above procedure.\
\
6.3.  LDP Label Withdrawal Procedures\
\
   As mentioned above, the Group ID field of the PWid FEC element, or\
   the PW Grouping ID TLV used with the Generalized ID FEC element, can\
   be used to withdraw all PW labels associated with a particular PW\
   group.  This procedure is OPTIONAL, and if it is implemented, the LDP\
   Label Withdraw message should be as follows: If the PWid FEC element\
   is used, the PW information length field is set to 0, the PW ID field\
   is not present, the interface parameter sub-TLVs are not present, and\
   the Label TLV is not present.\
\
\
\
Martini, et al.             Standards Track                    [Page 22]\
\
RFC 4447                     PWE3 Using LDP                   April 2006\
\
\
   If the Generalized FEC element is used, the AGI, SAII, and TAII are\
   not present, the PW information length field is set to 0, the PW\
   Grouping ID TLV is included, the Interface Parameters TLV is not\
   present, and the Label TLV is not present.  For the purpose of this\
   document, this is called the "wild card withdraw procedure", and all\
   PEs implementing this design are REQUIRED to accept such withdrawn\
   message but are not required to send it.  Note that the PW Grouping\
   ID TLV only applies to PWs using the Generalized ID FEC element,\
   while the Group ID only applies to PWid FEC element.\
\
   The interface parameter sub-TLVs, or TLV, MUST NOT be present in any\
   LDP PW Label Withdraw or Label Release message.  A wild card Label\
   Release message MUST include only the group ID, or Grouping ID TLV.\
   A Label Release message initiated by a PE router must always include\
   the PW ID.\
\
6.4.  Sequencing Considerations\
\
   In the case where the router considers the sequence number field in\
   the control word, it is important to note the following details when\
   advertising labels.\
\
6.4.1.  Label Advertisements\
\
   After a label has been withdrawn by the output router and/or released\
   by the input router, care must be taken not to advertise (re-use) the\
   same released label until the output router can be reasonably certain\
   that old packets containing the released label no longer persist in\
   the MPLS-enabled network.\
\
   This precaution is required to prevent the imposition router from\
   restarting packet forwarding with a sequence number of 1 when it\
   receives a Label Mapping message that binds the same FEC to the same\
   label if there are still older packets in the network with a sequence\
   number between 1 and 32768.  For example, if there is a packet with\
   sequence number=n, where n is in the interval [1,32768] traveling\
   through the network, it would be possible for the disposition router\
   to receive that packet after it re-advertises the label.  Since the\
   label has been released by the imposition router, the disposition\
   router SHOULD be expecting the next packet to arrive with a sequence\
   number of 1.  Receipt of a packet with a sequence number equal to n\
   will result in n packets potentially being rejected by the\
   disposition router until the imposition router imposes a sequence\
   number of n+1 into a packet.  Possible methods to avoid this are for\
   the disposition router always to advertise a different PW label, or\
   for the disposition router to wait for a sufficient time before\
\
\
\
\
\
Martini, et al.             Standards Track                    [Page 23]\
\
RFC 4447                     PWE3 Using LDP                   April 2006\
\
\
   attempting to re-advertise a recently released label.  This is only\
   an issue when sequence number processing is enabled at the\
   disposition router.\
\
6.4.2.  Label Release\
\
   In situations where the imposition router wants to restart forwarding\
   of packets with sequence number 1, the router shall 1) send to the\
   disposition router a Label Release Message, and 2) send to the\
   disposition router a Label Request message.  When sequencing is\
   supported, advertisement of a PW label in response to a Label Request\
   message MUST also consider the issues discussed in the section on\
   Label Advertisements.\
\
7.  IANA Considerations\
\
7.1.  LDP TLV TYPE\
\
   This document uses several new LDP TLV types; IANA already maintains\
   a registry of name "TLV TYPE NAME SPACE" defined by RFC 3036.  The\
   following values are suggested for assignment:\
\
      TLV type  Description\
      =====================================\
       0x096A   PW Status TLV\
       0x096B   PW Interface Parameters TLV\
       0x096C   Group ID TLV\
\
7.2.  LDP Status Codes\
\
   This document uses several new LDP status codes; IANA already\
   maintains a registry of name "STATUS CODE NAME SPACE" defined by RFC\
   3036.  The following values are suggested for assignment:\
\
   Range/Value     E     Description                       Reference\
   ------------- -----   ----------------------            ---------\
   0x00000024      0     Illegal C-Bit                     [RFC4447]\
   0x00000025      0     Wrong C-Bit                       [RFC4447]\
   0x00000026      0     Incompatible bit-rate             [RFC4447]\
   0x00000027      0     CEP-TDM mis-configuration         [RFC4447]\
   0x00000028      0     PW Status                         [RFC4447]\
   0x00000029      0     Unassigned/Unrecognized TAI       [RFC4447]\
   0x0000002A      0     Generic Misconfiguration Error    [RFC4447]\
   0x0000002B      0     Label Withdraw PW Status Method   [RFC4447]\
\
\
\
\
\
\
\
Martini, et al.             Standards Track                    [Page 24]\
\
RFC 4447                     PWE3 Using LDP                   April 2006\
\
\
7.3.  FEC Type Name Space\
\
   This document uses two new FEC element types, 0x80 and 0x81, from the\
   registry "FEC Type Name Space" for the Label Distribution Protocol\
   (LDP RFC 3036).\
\
8.  Security Considerations\
\
   This document specifies the LDP extensions that are needed for\
   setting up and maintaining pseudowires.  The purpose of setting up\
   pseudowires is to enable Layer 2 frames to be encapsulated in MPLS\
   and transmitted from one end of a pseudowire to the other.\
   Therefore, we treat the security considerations for both the data\
   plane and the control plane.\
\
8.1.  Data-Plane Security\
\
   With regard to the security of the data plane, the following areas\
   must be considered:\
\
      -  MPLS PDU inspection\
      -  MPLS PDU spoofing\
      -  MPLS PDU alteration\
      -  MPLS PSN protocol security\
      -  Access Circuit security\
      -  Denial-of-service prevention on the PE routers\
\
   When an MPLS PSN is used to provide pseudowire service, there is a\
   perception that security MUST be at least equal to the currently\
   deployed Layer 2 native protocol networks that the MPLS/PW network\
   combination is emulating.  This means that the MPLS-enabled network\
   SHOULD be isolated from outside packet insertion in such a way that\
   it SHOULD not be possible to insert an MPLS packet into the network\
   directly.  To prevent unwanted packet insertion, it is also important\
   to prevent unauthorized physical access to the PSN, as well as\
   unauthorized administrative access to individual network elements.\
\
   As mentioned above, as MPLS enabled network should not accept MPLS\
   packets from its external interfaces (i.e., interfaces to CE devices\
   or to other providers' networks) unless the top label of the packet\
   was legitimately distributed to the system from which the packet is\
   being received.  If the packet's incoming interface leads to a\
   different SP (rather than to a customer), an appropriate trust\
   relationship must also be present, including the trust that the other\
   SP also provides appropriate security measures.\
\
   The three main security problems faced when using an MPLS-enabled\
   network to transport PWs are spoofing, alteration, and inspection.\
\
\
\
Martini, et al.             Standards Track                    [Page 25]\
\
RFC 4447                     PWE3 Using LDP                   April 2006\
\
\
   First, there is a possibility that the PE receiving PW PDUs will get\
   a PDU that appears to be from the PE transmitting the PW into the\
   PSN, but that was not actually transmitted by the PE originating the\
   PW.  (That is, the specified encapsulations do not by themselves\
   enable the decapsulator to authenticate the encapsulator.)  A second\
   problem is the possibility that the PW PDU will be altered between\
   the time it enters the PSN and the time it leaves the PSN (i.e., the\
   specified encapsulations do not by themselves assure the decapsulator\
   of the packet's integrity.)  A third problem is the possibility that\
   the PDU's contents will be seen while the PDU is in transit through\
   the PSN (i.e., the specification encapsulations do not ensure\
   privacy.)  How significant these issues are in practice depends on\
   the security requirements of the applications whose traffic is being\
   sent through the tunnel, and how secure the PSN itself is.\
\
8.2.  Control-Plane Security\
\
   General security considerations with regard to the use of LDP are\
   specified in section 5 of RFC 3036.  Those considerations also apply\
   to the case where LDP is used to set up pseudowires.\
\
   A pseudowire connects two attachment circuits.  It is important to\
   make sure that LDP connections are not arbitrarily accepted from\
   anywhere, or else a local attachment circuit might get connected to\
   an arbitrary remote attachment circuit.  Therefore, an incoming LDP\
   session request MUST NOT be accepted unless its IP source address is\
   known to be the source of an "eligible" LDP peer.  The set of\
   eligible peers could be pre-configured (either as a list of IP\
   addresses, or as a list of address/mask combinations), or it could be\
   discovered dynamically via an auto-discovery protocol that is itself\
   trusted.  (Obviously, if the auto-discovery protocol were not\
   trusted, the set of "eligible peers" it produces could not be\
   trusted.)\
\
   Even if an LDP connection request appears to come from an eligible\
   peer, its source address may have been spoofed.  Therefore, some\
   means of preventing source address spoofing must be in place.  For\
   example, if all the eligible peers are in the same network, source\
   address filtering at the border routers of that network could\
   eliminate the possibility of source address spoofing.\
\
   The LDP MD5 authentication key option, as described in section 2.9 of\
   RFC 3036, MUST be implemented, and for a greater degree of security,\
   it must be used.  This provides integrity and authentication for the\
   LDP messages and eliminates the possibility of source address\
   spoofing.  Use of the MD5 option does not provide privacy, but\
   privacy of the LDP control messages is not usually considered\
   important.  As the MD5 option relies on the configuration of pre-\
\
\
\
Martini, et al.             Standards Track                    [Page 26]\
\
RFC 4447                     PWE3 Using LDP                   April 2006\
\
\
   shared keys, it does not provide much protection against replay\
   attacks.  In addition, its reliance on pre-shared keys may make it\
   very difficult to deploy when the set of eligible neighbors is\
   determined by an auto-configuration protocol.\
\
   When the Generalized ID FEC Element is used, it is possible that a\
   particular LDP peer may be one of the eligible LDP peers but may not\
   be the right one to connect to the particular attachment circuit\
   identified by the particular instance of the Generalized ID FEC\
   element.  However, given that the peer is known to be one of the\
   eligible peers (as discussed above), this would be the result of a\
   configuration error, rather than a security problem.  Nevertheless,\
   it may be advisable for a PE to associate each of its local\
   attachment circuits with a set of eligible peers rather than have\
   just a single set of eligible peers associated with the PE as a\
   whole.\
\
9.  Acknowledgements\
\
   The authors wish to acknowledge the contributions of Vach Kompella,\
   Vanson Lim, Wei Luo, Himanshu Shah, and Nick Weeds.\
\
10.  Normative References\
\
   [RFC2119] Bradner S., "Key words for use in RFCs to Indicate\
             Requirement Levels", RFC 2119, March 1997\
\
   [RFC3036] Andersson, L., Doolan, P., Feldman, N., Fredette, A., and\
             B. Thomas, "LDP Specification", RFC 3036, January 2001.\
\
   [RFC3032] Rosen, E., Tappan, D., Fedorkow, G., Rekhter, Y.,\
             Farinacci, D., Li, T., and A. Conta, "MPLS Label Stack\
             Encoding", RFC 3032, January 2001.\
\
   [IANA]    Martini, L., "IANA Allocations for Pseudowire Edge to Edge\
             Emulation (PWE3)", BCP 116, RFC 4446, April 2006.\
\
11.  Informative References\
\
   [CEP]     Malis, A., Pate, P., Cohen, R., Ed., and D. Zelig,\
             "SONET/SDH Circuit Emulation Service Over Packet (CEP)",\
             Work in Progress.\
\
   [SAToP]   Vainshtein, A., Ed. and Y. Stein, Ed., "Structure-Agnostic\
             TDM over Packet (SAToP)", Work in Progress.\
\
\
\
\
\
\
Martini, et al.             Standards Track                    [Page 27]\
\
RFC 4447                     PWE3 Using LDP                   April 2006\
\
\
   [FRAME]   Martini, L., Ed. and C. Kawa, Ed., "Encapsulation Methods\
             for Transport of Frame Relay Over MPLS Networks", Work in\
             Progress.\
\
   [ATM]     Martini, L., Ed., El-Aawar, N., and M. Bocci, Ed.,\
             "Encapsulation Methods for Transport of ATM Over MPLS\
             Networks", Work in Progress.\
\
   [PPPHDLC] Martini, L., Rosen, E., Heron, G., and A. Malis,\
             "Encapsulation Methods for Transport of PPP/HDLC Frames\
             Over IP and MPLS Networks", Work in Progress.\
\
   [ETH]     Martini, L., Rosen, E., El-Aawar, N., and G. Heron,\
             "Encapsulation Methods for Transport of Ethernet Over MPLS\
             Networks", RFC 4448, April 2006.\
\
   [SDH]     American National Standards Institute, "Synchronous Optical\
             Network Formats," ANSI T1.105-1995.\
\
   [ITUG]    ITU Recommendation G.707, "Network Node Interface For The\
             Synchronous Digital Hierarchy", 1996.\
\
   [RFC3985] Bryant, S. and P. Pate, "Pseudo Wire Emulation Edge-to-Edge\
             (PWE3) Architecture", RFC 3985, March 2005.\
\
   [RFC2277] Alvestrand, H., "IETF Policy on Character Sets and\
             Languages", BCP 18, RFC 2277, January 1998.\
\
12.  Additional Contributing Authors\
\
   Dimitri Stratton Vlachos\
   Mazu Networks, Inc.\
   125 Cambridgepark Drive\
   Cambridge, MA 02140\
\
   EMail: d@mazunetworks.com\
\
\
   Jayakumar Jayakumar,\
   Cisco Systems Inc.\
   225, E.Tasman, MS-SJ3/3,\
   San Jose, CA, 95134\
\
   EMail: jjayakum@cisco.com\
\
\
\
\
\
\
\
Martini, et al.             Standards Track                    [Page 28]\
\
RFC 4447                     PWE3 Using LDP                   April 2006\
\
\
   Alex Hamilton,\
   Cisco Systems Inc.\
   285 W. Tasman, MS-SJCI/3/4,\
   San Jose, CA, 95134\
\
   EMail: tahamilt@cisco.com\
\
\
   Steve Vogelsang\
   ECI Telecom\
   Omega Corporate Center\
   1300 Omega Drive\
   Pittsburgh, PA 15205\
\
   EMail: stephen.vogelsang@ecitele.com\
\
\
   John Shirron\
   ECI Telecom\
   Omega Corporate Center\
   1300 Omega Drive\
   Pittsburgh, PA 15205\
\
   EMail: john.shirron@ecitele.com\
\
\
   Andrew G. Malis\
   Tellabs\
   90 Rio Robles Dr.\
   San Jose, CA 95134\
\
   EMail: Andy.Malis@tellabs.com\
\
\
   Vinai Sirkay\
   Redback Networks\
   300 Holger Way\
   San Jose, CA 95134\
\
   EMail: vsirkay@redback.com\
\
\
   Vasile Radoaca\
   Nortel Networks\
   600  Technology Park\
   Billerica MA 01821\
\
   EMail: vasile@nortelnetworks.com\
\
\
\
Martini, et al.             Standards Track                    [Page 29]\
\
RFC 4447                     PWE3 Using LDP                   April 2006\
\
\
   Chris Liljenstolpe\
   Alcatel\
   11600 Sallie Mae Dr.\
   9th Floor\
   Reston, VA 20193\
\
   EMail: chris.liljenstolpe@alcatel.com\
\
\
   Dave Cooper\
   Global Crossing\
   960 Hamlin Court\
   Sunnyvale, CA 94089\
\
   EMail: dcooper@gblx.net\
\
\
   Kireeti Kompella\
   Juniper Networks\
   1194 N. Mathilda Ave\
   Sunnyvale, CA 94089\
\
   EMail: kireeti@juniper.net\
\
\
   Dan Tappan\
   Cisco Systems, Inc.\
   1414 Massachusetts Avenue\
   Boxborough, MA 01719\
\
   EMail: tappan@cisco.com\
\
\
\
\
\
\
\
\
\
\
\
\
\
\
\
\
\
\
\
\
Martini, et al.             Standards Track                    [Page 30]\
\
RFC 4447                     PWE3 Using LDP                   April 2006\
\
\
Appendix A.  C-bit Handling Procedures Diagram\
\
                   ------------------\
               Y   | Received Label |       N\
            -------|  Mapping Msg?  |--------------\
            |      ------------------             |\
        --------------                            |\
        |            |                            |\
     -------      -------                         |\
     | C=0 |      | C=1 |                         |\
     -------      -------                         |\
        |            |                            |\
        |    ----------------                     |\
        |    | Control Word |     N               |\
        |    |    Capable?  |-----------          |\
        |    ----------------          |          |\
        |          Y |                 |          |\
        |            |                 |          |\
        |   ----------------           |          |\
        |   | Control Word |  N        |          |\
        |   |  Preferred?  |----       |          |\
        |   ----------------   |       |          |\
        |          Y |         |       |          |\
        |            |         |       |   ----------------\
        |            |         |       |   | Control Word |\
        |            |         |       |   |  Preferred?  |\
        |            |         |       |   ----------------\
        |            |         |       |     N |     Y |\
        |            |         |       |       |       |\
      Send         Send      Send    Send    Send    Send\
       C=0          C=1       C=0     C=0     C=0     C=1\
                               |       |       |       |\
                            ----------------------------------\
                            | If receive the same as sent,   |\
                            | PW setup is complete. If not:  |\
                            ----------------------------------\
                               |       |       |       |\
                              ------------------- -----------\
                              |     Receive     | | Receive |\
                              |       C=1       | |   C=0   |\
                              ------------------- -----------\
                                       |               |\
                                 Wait for the        Send\
                                 next message     Wrong C-Bit\
                                                       |\
                                                  Send Label\
                                               Mapping Message\
\
\
\
\
Martini, et al.             Standards Track                    [Page 31]\
\
RFC 4447                     PWE3 Using LDP                   April 2006\
\
\
Authors' Addresses\
\
   Luca Martini\
   Cisco Systems, Inc.\
   9155 East Nichols Avenue, Suite 400\
   Englewood, CO, 80112\
\
   EMail: lmartini@cisco.com\
\
\
   Nasser El-Aawar\
   Level 3 Communications, LLC.\
   1025 Eldorado Blvd.\
   Broomfield, CO, 80021\
\
   EMail: nna@level3.net\
\
\
   Giles Heron\
   Tellabs\
   Abbey Place\
   24-28 Easton Street\
   High Wycombe\
   Bucks\
   HP11 1NT\
   UK\
\
   EMail: giles.heron@tellabs.com\
\
\
   Eric C. Rosen\
   Cisco Systems, Inc.\
   1414 Massachusetts Avenue\
   Boxborough, MA 01719\
\
   EMail: erosen@cisco.com\
\
\
   Toby Smith\
   Network Appliance, Inc.\
   800 Cranberry Woods Drive\
   Suite 300\
   Cranberry Township, PA 16066\
\
   EMail: tob@netapp.com\
\
\
\
\
\
\
Martini, et al.             Standards Track                    [Page 32]\
\
RFC 4447                     PWE3 Using LDP                   April 2006\
\
\
Full Copyright Statement\
\
   Copyright (C) The Internet Society (2006).\
\
   This document is subject to the rights, licenses and restrictions\
   contained in BCP 78, and except as set forth therein, the authors\
   retain all their rights.\
\
   This document and the information contained herein are provided on an\
   "AS IS" basis and THE CONTRIBUTOR, THE ORGANIZATION HE/SHE REPRESENTS\
   OR IS SPONSORED BY (IF ANY), THE INTERNET SOCIETY AND THE INTERNET\
   ENGINEERING TASK FORCE DISCLAIM ALL WARRANTIES, EXPRESS OR IMPLIED,\
   INCLUDING BUT NOT LIMITED TO ANY WARRANTY THAT THE USE OF THE\
   INFORMATION HEREIN WILL NOT INFRINGE ANY RIGHTS OR ANY IMPLIED\
   WARRANTIES OF MERCHANTABILITY OR FITNESS FOR A PARTICULAR PURPOSE.\
\
Intellectual Property\
\
   The IETF takes no position regarding the validity or scope of any\
   Intellectual Property Rights or other rights that might be claimed to\
   pertain to the implementation or use of the technology described in\
   this document or the extent to which any license under such rights\
   might or might not be available; nor does it represent that it has\
   made any independent effort to identify any such rights.  Information\
   on the procedures with respect to rights in RFC documents can be\
   found in BCP 78 and BCP 79.\
\
   Copies of IPR disclosures made to the IETF Secretariat and any\
   assurances of licenses to be made available, or the result of an\
   attempt made to obtain a general license or permission for the use of\
   such proprietary rights by implementers or users of this\
   specification can be obtained from the IETF on-line IPR repository at\
   http://www.ietf.org/ipr.\
\
   The IETF invites any interested party to bring to its attention any\
   copyrights, patents or patent applications, or other proprietary\
   rights that may cover technology that may be required to implement\
   this standard.  Please address the information to the IETF at\
   ietf-ipr@ietf.org.\
\
Acknowledgement\
\
   Funding for the RFC Editor function is provided by the IETF\
   Administrative Support Activity (IASA).\
\
\
\
\
\
\
\
Martini, et al.             Standards Track                    [Page 33]\
\

doc 2
  field 0
    name titolo
    type string
    value rfc4441.txt
  field 1
    name contenuto
    type string
    value \
\
\
\
\
\
Network Working Group                                      B. Aboba, Ed.\
Request for Comments: 4441                   Internet Architecture Board\
Category: Informational                                       March 2006\
\
\
                     The IEEE 802/IETF Relationship\
\
Status of This Memo\
\
   This memo provides information for the Internet community.  It does\
   not specify an Internet standard of any kind.  Distribution of this\
   memo is unlimited.\
\
Copyright Notice\
\
   Copyright (C) The Internet Society (2006).\
\
Abstract\
\
   Since the late 1980s, IEEE 802 and IETF have cooperated in the\
   development of Simple Network Management Protocol (SNMP) MIBs and\
   Authentication, Authorization, and Accounting (AAA) applications.\
   This document describes the policies and procedures that have\
   developed in order to coordinate between the two organizations, as\
   well as some of the relationship history.\
\
Table of Contents\
\
   1. Introduction ....................................................2\
      1.1. Liaison Communications .....................................2\
      1.2. Access to IEEE 802 Archives ................................3\
      1.3. New Work Review ............................................3\
      1.4. MIB Review .................................................4\
      1.5. EAP Review .................................................4\
      1.6. AAA Review .................................................5\
      1.7. Document Review ............................................5\
      1.8. EtherType Allocation .......................................6\
   2. Security Considerations .........................................6\
   3. Informative References ..........................................7\
   4. Acknowledgements ...............................................12\
   Appendix A.  Relationship History .................................13\
      A.1.  MIB Development ..........................................13\
      A.2.  AAA/EAP ..................................................16\
   Appendix B.  IAB Members at the Time of This Writing ..............21\
\
\
\
\
\
\
\
IAB                          Informational                      [Page 1]\
\
RFC 4441               IEEE 802/IETF Relationship             March 2006\
\
\
1.  Introduction\
\
   Since the late 1980s, participants in IEEE 802 and the IETF have\
   cooperated in the development of Management Information Bases (MIBs)\
   and Authentication, Authorization, and Accounting (AAA) applications\
   relating to IEEE standards.  This has included the Bridge MIB\
   [RFC1493] [RFC4188], the multicast filtering and VLAN extension MIB\
   [RFC2674] [RFC4363], the Hub MIB [RFC2108], the Ethernet-like\
   Interfaces MIB [RFC3635], the MAU MIB [RFC3636], the WAN Interfaces\
   Sublayer MIB [RFC3637], the Power Ethernet MIB [RFC3621], IEEE 802.1X\
   RADIUS usage guidelines [RFC3580], the revised Extensible\
   Authentication Protocol (EAP) specification [RFC3748], RADIUS/EAP\
   [RFC3579], and the EAP State Machine specification [RFC4137].  This\
   document describes the policies and procedures that have been put in\
   place to encourage cooperation between the IETF and IEEE 802.\
   Details of the relationship history are included in Appendix A.\
\
   In order to improve communications between the IETF and IEEE 802,\
   members of the Internet Engineering Steering Group (IESG) and\
   Internet Architecture Board (IAB) (including Bert Wijnen, James\
   Kempf, and Bernard Aboba) met with the IEEE 802 Executive Committee\
   in Vancouver, Canada, in January 2004.  At that meeting, a number of\
   issues were discussed and new procedures were put in place.\
\
1.1.  Liaison Communications\
\
   IETF Working Groups are organized into areas, which have one or more\
   Area Directors.  The Area Directors, plus the IETF Chair, comprise\
   the Internet Engineering Steering Group (IESG).  IEEE 802 Working\
   Groups have one or more Task Groups.  The IEEE 802 Working Group\
   Chairs, plus the IEEE 802 Chair, comprise the IEEE 802 Executive\
   Committee (ExComm).\
\
   Participants in the IETF are appointed as liaisons to other\
   organizations by the IAB or IESG as appropriate.  This includes a\
   liaison to IEEE 802 as well as liaisons to specific IEEE 802 Working\
   Groups.  The IETF liaison web page includes a list of IETF liaisons,\
   as well as a pointer to the archive of liaison statements received by\
   the IETF [Liaison-Page].  IETF processes for management of liaison\
   relationships are described in [BCP102]; procedures for handling of\
   incoming liaison statements are described in [BCP103].  In order to\
   ensure that liaison statements from IEEE 802 to the IETF are archived\
   and responded to, IEEE 802 liaisons to IETF should utilize the IETF\
   liaison management tool to submit liaison communications.  A username\
   and password suitable for use with the tool can be obtained by\
   sending mail to iesg-secretary@ietf.org.  If a liaison management\
   account is not available, liaison communications can be sent to the\
   IETF liaison(s) to IEEE 802 and copied to statements@ietf.org.\
\
\
\
IAB                          Informational                      [Page 2]\
\
RFC 4441               IEEE 802/IETF Relationship             March 2006\
\
\
   However, in this case substantially greater processing delays will\
   occur due to the need for manual handling by the IETF Secretariat\
   staff.\
\
   Liaison requests from the IETF to IEEE 802 should be sent to the\
   Chair(s) of the IEEE 802 WG to which the request pertains, with a\
   copy sent to the IEEE 802 Chair and the IEEE 802 liaison(s) to IETF.\
   IEEE 802 procedures for communicating with other standards bodies are\
   described in Section 14.1 of [Policy].  Liaison communications to\
   IEEE 802 WGs are archived by the individual WGs.\
\
1.2.  Access to IEEE 802 Archives\
\
   Access to IEEE 802 standards more than six months old is provided\
   free of charge on the IEEE 802 website via the Get IEEE 802 Program\
   [GetIEEE-802].  Access to IEEE 802 work-in-progress has frequently\
   arisen as an issue in cooperation between IETF and IEEE 802.  While\
   in the past IETF Working Groups (WGs) have successfully negotiated\
   access to IEEE 802 work-in-progress, each instance has been handled\
   separately and took significant time and effort to complete.  In\
   order to more easily enable document access for IETF WGs\
   collaborating with IEEE 802, a liaison statement was sent to the IETF\
   in July 2004 by Paul Nikolich, Chair of IEEE 802 [IEEE-802Liaison],\
   describing the process by which IETF WGs can obtain access to IEEE\
   802 work-in-progress.  IEEE 802 WG Chairs have the authority to grant\
   membership in their WGs, and can use this authority to grant\
   membership to an IETF WG chair upon request.  The IETF WG chair will\
   be provided with access to the username/password for the IEEE 802 WG\
   archives, and is permitted to share that information with\
   participants in the IETF WG.  Since it is possible to participate in\
   IETF without attending meetings, or even joining a mailing list, IETF\
   WG chairs will provide the information to anyone who requests it.\
   However, since IEEE 802 work-in-progress is copyrighted,\
   incorporating material into IETF documents or posting the\
   username/password on mailing lists or websites is not permitted.\
\
1.3.  New Work Review\
\
   In order to enable IEEE 802 review of proposed IETF WG charters, as\
   well as to enable IETF review of proposed IEEE 802 Project\
   Authorization Requests (PARs), the New Work mailing list is used.\
   The IEEE 802 Executive Committee is subscribed to the list, so that\
   it can receive proposed IETF WG Charters.  Proposed IEEE 802 PARs are\
   posted to the New Work list as well.  Where a New Work announcement\
   is of particular interest, it is also (manually) forwarded to the\
   relevant IETF and IEEE 802 mailing lists.\
\
\
\
\
\
IAB                          Informational                      [Page 3]\
\
RFC 4441               IEEE 802/IETF Relationship             March 2006\
\
\
   However, by the time an IETF WG Charter or IEEE 802 PAR appears on\
   New Work, a IETF BOF or IEEE 802 "Call for Interest" has already\
   occurred, interest has been demonstrated and considerable work has\
   gone into development of the Charter or PAR.  If problems are found\
   at that point, it is often too late in the process to make major\
   changes.  Therefore, where a potential work item is likely to be\
   controversial, discussions between IETF and IEEE 802 are encouraged\
   to occur earlier in the process.\
\
1.4.  MIB Review\
\
   With travel budgets under pressure, it has become increasingly\
   difficult for companies to fund employees to attend both IEEE 802 and\
   IETF meetings.  As a result, an alternative is needed to past\
   arrangements that involved chartering MIB work items within an IETF\
   WG.  In order to encourage wider review of MIBs developed by IEEE 802\
   WGs, it is recommended that Simple Network Management Protocol (SNMP)\
   MIBs developed in IEEE 802 follow the MIB guidelines [RFC4181] and be\
   reviewed as part of the IETF SNMP quality control process ('MIB\
   Doctors').  An IEEE 802 group may request assignment of a 'MIB\
   Doctor' to assist in a MIB review by contacting the IETF Operations\
   and Management Area Director.\
\
   By standardizing IEEE 802 MIBs only within IEEE 802 while utilizing\
   the SNMP quality control process, the IETF and IEEE 802 seek to\
   ensure quality while decreasing overhead.  A trial run of this\
   process has taken place in IEEE 802.1 where a MIB Doctor (David\
   Harrington) has agreed to review IEEE 802.1 MIBs.  Currently,\
   discussion is under way on how change control of selected IEEE 802.1\
   MIB documents published as RFCs can be transferred to IEEE 802.1\
   [MIB-TRANSFER].\
\
1.5.  EAP Review\
\
   Several IEEE 802 standards, including [IEEE-802.1X-2004],\
   [IEEE-802.11i], and [IEEE-802.16e], depend on EAP [RFC3748] and EAP\
   key management, described in [KEYFRAME].  Rather than developing\
   their own EAP methods, or extensions for EAP key management, IEEE 802\
   working groups should send a liaison letter to the IETF, outlining\
   the required functionality or requesting a review of draft text.\
   Most recently, a security review of IEEE 802.16e D8 [EAPREVIEW] has\
   been carried out by the EAP WG, at the request of the IEEE 802.16\
   Chair, Roger Marks [IEEE-802.16-Liaison1] [IEEE-802.16-Liaison2].\
\
\
\
\
\
\
\
\
IAB                          Informational                      [Page 4]\
\
RFC 4441               IEEE 802/IETF Relationship             March 2006\
\
\
1.6.  AAA Review\
\
   IEEE 802 WGs requiring new AAA applications should send a liaison\
   request to the IETF.  Where new attributes are required rather than a\
   new application, an Internet-Draft can be submitted and review can\
   be requested from AAA-related WGs such as the AAA or RADEXT WGs.  For\
   attributes of general utility, and particularly those useful in\
   multiple potential applications, allocation from the IETF standard\
   attribute space is preferred to creation of IEEE 802 Vendor-Specific\
   Attributes (VSAs).  As noted in [RFC3575]:\
\
   RADIUS defines a mechanism for Vendor-Specific extensions (Attribute\
   26) and the use of that should be encouraged instead of allocation of\
   global attribute types, for functions specific only to one vendor's\
   implementation of RADIUS, where no interoperability is deemed useful.\
\
   Where allocation of VSAs are required, it is recommended that IEEE\
   802 create a uniform format for all of IEEE 802, rather than having\
   each IEEE 802 group create their own VSA format.  The VSA format\
   defined in [IEEE-802.11F] is inappropriate for this, since the Type\
   field is only a single octet, allowing for only 255 attributes.\
   Recently, the AAA Doctors list has been created within the IETF\
   Operations and Management Area Directorate, serving a similar\
   function to the MIB Doctors.  While the AAA Doctors have not yet been\
   called upon to assist with and review AAA work outside of the IETF,\
   this group could potentially be of assistance to IEEE 802 working\
   groups requiring help with AAA.\
\
1.7.  Document Review\
\
   With the areas of cooperation between IEEE 802 and IETF increasing,\
   the document review process has extended beyond the traditional\
   subjects of SNMP MIBs and AAA.  For example, as part of the IETF\
   CAPWAP WG charter, IEEE 802.11 was asked to review the CAPWAP\
   Taxonomy Document [RFC4118]; Dorothy Stanley organized an ad hoc\
   group for this purpose.  IEEE 802.11 has also reviewed [IDSEL] and\
   [IABLINK].  Within IETF, IEEE 802 comments are resolved using normal\
   WG and IETF processes.\
\
   IETF participants can comment as part of the IEEE 802 ballot process,\
   regardless of their voting status within IEEE 802.  Comments must be\
   composed in the format specified for the ballot, and submitted by the\
   ballot deadline.\
\
\
\
\
\
\
\
\
IAB                          Informational                      [Page 5]\
\
RFC 4441               IEEE 802/IETF Relationship             March 2006\
\
\
1.8.  EtherType Allocation\
\
   The EtherType field is very limited, so that allocations are made\
   solely on an "as needed" basis.  For related uses, a single EtherType\
   should be requested, with additional fields serving as sub-protocol\
   identifiers, rather than applying for multiple EtherTypes.  EtherType\
   allocation policy is described in [TYPE-TUT].\
\
   While a fee is normally charged by IEEE 802 for the allocation of an\
   EtherType, IEEE 802 will consider waiving the fee for allocations\
   relating to an IETF standards track document, based on a request from\
   the IESG.\
\
2.  Security Considerations\
\
   As IEEE 802 becomes increasingly involved in the specification of\
   standards for link-layer security, experience has shown that it is\
   helpful to obtain outside review of work-in-progress prior to\
   publication.  This has proven somewhat challenging since access to\
   IEEE 802 work-in-progress documents is often tightly controlled.  For\
   example, special permission had to be obtained for IEEE 802.11i to be\
   able to circulate a version of its security standard-in-progress for\
   review.  A liaison between an IEEE 802 group and an IETF WG can help\
   in obtaining the necessary level of review.\
\
   Experience has also shown that IETF standards may not be written to\
   the level of clarity required by the IEEE 802 standards process.  In\
   the case of EAP [RFC3748], the process of developing the EAP state\
   machine specification [RFC4137] proved useful in uncovering aspects\
   requiring clarification, and the joint review process exposed IEEE\
   802 and IETF documents-in-progress to wider review than might\
   otherwise have been possible.\
\
   Similarly, the development of [IEEE-802.11i], [RFC3748], [KEYFRAME],\
   and [RFC4017] led to a deeper understanding of the limitations and\
   security vulnerabilities of the EAP/AAA system.  As described in\
   [Housley], it is not advisable to develop new AAA key management\
   applications without completing a security analysis, such as the\
   analysis provided in [KEYFRAME].\
\
   Due to weaknesses in the RADIUS specification [RFC2865], it is\
   relatively easy for protocol extensions to introduce serious security\
   vulnerabilities.  As a result, IETF review of IEEE 802 RADIUS\
   extensions is advisable, and the RADIUS IANA Considerations [RFC3575]\
   have been revised so as to require such a review in most cases.\
\
\
\
\
\
\
IAB                          Informational                      [Page 6]\
\
RFC 4441               IEEE 802/IETF Relationship             March 2006\
\
\
3.  Informative References\
\
   [BCP102]        Daigle, L. and Internet Architecture Board, "IAB\
                   Processes for Management of IETF Liaison\
                   Relationships", BCP 102, RFC 4052, April 2005.\
\
   [BCP103]        Trowbridge, S., Bradner, S., and F. Baker,\
                   "Procedures for Handling Liaison Statements to and\
                   from the IETF", BCP 103, RFC 4053, April 2005.\
\
   [EAPREVIEW]     EAP WG letter to Roger Marks, June 2005,\
                   http://www.drizzle.com/~aboba/EAP/review.txt.\
\
   [GetIEEE-802]   IEEE Standards Association Get IEEE 802 (R) Program,\
                   http://standards.ieee.org/getieee802/portfolio.html.\
\
   [IDSEL]         Adrangi, F., Lortz, V., Bari, F., and P. Eronen,\
                   "Identity Selection Hints for the Extensible\
                   Authentication Protocol (EAP)", RFC 4284, January\
                   2006.\
\
   [Housley]       Housley, R. and B. Aboba, "AAA Key Management", Work\
                   in Progress, November 2005.\
\
   [IABLINK]       Aboba, B., "Architectural Implications of Link\
                   Indications", Work in Progress, August 2005.\
\
   [IEEE-80211Liaison1]\
                   IEEE 802.11 liaison letter to Harald Alvestrand,\
                   February 2002,\
                   https://www.ietf.org/IESG/LIAISON/ieee802.11.txt.\
\
   [IEEE-80211Liaison2]\
                   Input To IETF EAP Working Group on Methods and Key\
                   Strength, March 2003,\
                   http://www.ietf.org/IESG/LIAISON/LS-ieee-80211.txt.\
\
   [IEEE-802.11F]  Institute of Electrical and Electronics Engineers,\
                   "IEEE Trial-Use Recommended Practice for Multi-Vendor\
                   Access Point Interoperability via an Inter-Access\
                   Point Protocol Across Distribution Systems Supporting\
                   IEEE 802.11 Operation", IEEE 802.11F, June 2003 (now\
                   deprecated).\
\
   [IEEE-802Liaison]\
                   IEEE 802 Liaison letter to Bert Wijnen and Bernard\
                   Aboba, July 26, 2004,\
                   http://www.ietf.org/IESG/LIAISON/file41.pdf.\
\
\
\
IAB                          Informational                      [Page 7]\
\
RFC 4441               IEEE 802/IETF Relationship             March 2006\
\
\
   [IEEE-802.1X-MIB]\
                   Norseth, K., "Definitions for Port Access Control\
                   (IEEE 802.1X) MIB", Work in Progress, November 2003.\
\
   [IEEE-802.1X]   IEEE Standards for Local and Metropolitan Area\
                   Networks: Port based Network Access Control, IEEE\
                   P802.1X-2001, June 2001.\
\
   [IEEE-802.1X-2004]\
                   IEEE Standards for Local and Metropolitan Area\
                   Networks: Port based Network Access Control, IEEE\
                   P802.1X-2004, December 2004.\
\
   [IEEE-802.1D]   ISO/IEC 15802-3 Information technology -\
                   Telecommunications and information exchange between\
                   systems - Local and metropolitan area networks -\
                   Common specifications - Part 3: Media access Control\
                   (MAC) Bridges, (also ANSI/IEEE Std 802.1D-1998),\
                   1998.\
\
   [IEEE-802.1Q]   IEEE Standards for Local and Metropolitan Area\
                   Networks: Draft Standard for Virtual Bridged Local\
                   Area Networks, P802.1Q, January 1998.\
\
   [IEEE-802.3]    ISO/IEC 8802-3 Information technology -\
                   Telecommunications and information exchange between\
                   systems - Local and metropolitan area networks -\
                   Common specifications - Part 3:  Carrier Sense\
                   Multiple Access with Collision Detection (CSMA/CD)\
                   Access Method and Physical Layer Specifications,\
                   (also ANSI/IEEE Std 802.3- 1996), 1996.\
\
   [IEEE-802.11]   Information technology - Telecommunications and\
                   information exchange between systems - Local and\
                   metropolitan area networks - Specific Requirements\
                   Part 11:  Wireless LAN Medium Access Control (MAC)\
                   and Physical Layer (PHY) Specifications, IEEE\
                   P802.11-2003, 2003.\
\
   [IEEE-802.11i]  IEEE Supplement to Standard for Telecommunications\
                   and Information Exchange Between Systems - LAN/MAN\
                   Specific Requirements - Part 11:  Wireless LAN Medium\
                   Access Control (MAC) and Physical Layer (PHY)\
                   Specifications:  Specification for Enhanced Security,\
                   IEEE P802.11i, July 2004.\
\
\
\
\
\
\
IAB                          Informational                      [Page 8]\
\
RFC 4441               IEEE 802/IETF Relationship             March 2006\
\
\
   [IEEE-802.16e]  IEEE Standard for Local and Metropolitan Area\
                   Networks - Part 16:  Air Interface for Fixed and\
                   Mobile Broadband Wireless Access Systems, Amendment\
                   for Physical and Medium Access Control Layers for\
                   Combined Fixed and Mobile Operation in Licensed\
                   Bands, IEEE P802.16e, September 2005.\
\
   [IEEE-802.16-Liaison1]\
                   Liaison letter from IEEE 802.16 to Bernard Aboba,\
                   March 17, 2005,\
                   http://ieee802.org/16/liaison/docs/L80216-05_025.pdf.\
\
   [IEEE-802.16-Liaison2]\
                   Liaison letter from IEEE 802.16 to Bernard Aboba, May\
                   5, 2005,\
                   http://ieee802.org/16/liaison/docs/L80216-05_039.pdf.\
\
   [KEYFRAME]      Aboba, B., Simon, D., Arkko, J., Eronen, P., and H.\
                   Levkowetz, "Extensible Authentication Protocol (EAP)\
                   Key Management Framework", Work in Progress, October\
                   2005.\
\
   [Liaison-Page]  IETF Liaison Activities,\
                   http://www.ietf.org/liaisonActivities.html.\
\
   [MIB-TRANSFER]  Harrington, D., "Transferring MIB Work from IETF\
                   Bridge WG to IEEE 802.1 WG",  Work in Progress,\
                   October 2005.\
\
   [Mishra]        Mishra, A. and W. Arbaugh, "An Initial Security\
                   Analysis of the IEEE 802.1X Standard", Department of\
                   Computer Science, University of Maryland College\
                   Park, CS-TR-4328, February 2002.\
\
   [Policy]        IEEE Project 802 LAN MAN Standards Committee (LMSC)\
                   Policies and Procedures, September 14, 2005,\
                   http://www.ieee802.org/policies-and-procedures.pdf.\
\
   [RFC1493]       Decker, E., Langille, P., Rijsinghani, A., and K.\
                   McCloghrie, "Definitions of Managed Objects for\
                   Bridges", RFC 1493, July 1993.\
\
   [RFC2108]       de Graaf, K., Romascanu, D., McMaster, D., and K.\
                   McCloghrie, "Definitions of Managed Objects for IEEE\
                   802.3 Repeater Devices using SMIv2", RFC 2108,\
                   February 1997.\
\
\
\
\
\
IAB                          Informational                      [Page 9]\
\
RFC 4441               IEEE 802/IETF Relationship             March 2006\
\
\
   [RFC2284]       Blunk, L. and J. Vollbrecht, "PPP Extensible\
                   Authentication Protocol (EAP)", RFC 2284, March 1998.\
\
   [RFC2390]       Bradley, T., Brown, C., and A. Malis, "Inverse\
                   Address Resolution Protocol", RFC 2390, September\
                   1998.\
\
   [RFC2674]       Bell, E., Smith, A., Langille, P., Rijhsinghani, A.,\
                   and K. McCloghrie, "Definitions of Managed Objects\
                   for Bridges with Traffic Classes, Multicast Filtering\
                   and Virtual LAN Extensions", RFC 2674, August 1999.\
\
   [RFC2865]       Rigney, C., Willens, S., Rubens, A., and W. Simpson,\
                   "Remote Authentication Dial In User Service\
                   (RADIUS)", RFC 2865, June 2000.\
\
   [RFC2866]       Rigney, C., "RADIUS Accounting", RFC 2866, June 2000.\
\
   [RFC2867]       Zorn, G., Aboba, B., and D. Mitton, "RADIUS\
                   Accounting Modifications for Tunnel Protocol\
                   Support", RFC 2867, June 2000.\
\
   [RFC2868]       Zorn, G., Leifer, D., Rubens, A., Shriver, J.,\
                   Holdrege, M., and I. Goyret, "RADIUS Attributes for\
                   Tunnel Protocol Support", RFC 2868, June 2000.\
\
   [RFC2869]       Rigney, C., Willats, W., and P. Calhoun, "RADIUS\
                   Extensions", RFC 2869, June 2000.\
\
   [RFC3162]       Aboba, B., Zorn, G., and D. Mitton, "RADIUS and\
                   IPv6", RFC 3162, August 2001.\
\
   [RFC3575]       Aboba, B., "IANA Considerations for RADIUS (Remote\
                   Authentication Dial In User Service)", RFC 3575, July\
                   2003.\
\
   [RFC3579]       Aboba, B. and P. Calhoun, "RADIUS (Remote\
                   Authentication Dial In User Service) Support For\
                   Extensible Authentication Protocol (EAP)", RFC 3579,\
                   September 2003.\
\
   [RFC3580]       Congdon, P., Aboba, B., Smith, A., Zorn, G., and J.\
                   Roese, "IEEE 802.1X Remote Authentication Dial In\
                   User Service (RADIUS) Usage Guidelines", RFC 3580,\
                   September 2003.\
\
   [RFC3621]       Berger, A. and D. Romascanu, "Power Ethernet MIB",\
                   RFC 3621, December 2003.\
\
\
\
IAB                          Informational                     [Page 10]\
\
RFC 4441               IEEE 802/IETF Relationship             March 2006\
\
\
   [RFC3635]       Flick, J., "Definitions of Managed Objects for the\
                   Ethernet-like Interface Types", RFC 3635, September\
                   2003.\
\
   [RFC3636]       Flick, J., "Definitions of Managed Objects for IEEE\
                   802.3 Medium Attachment Units (MAUs)", RFC 3636,\
                   September 2003.\
\
   [RFC3637]       Heard, C.M., Ed., "Definitions of Managed Objects for\
                   the Ethernet WAN Interface Sublayer", RFC 3637,\
                   September 2003.\
\
   [RFC3748]       Aboba, B., Blunk, L., Vollbrecht, J., Carlson, J.,\
                   and H. Levkowetz, "Extensible Authentication Protocol\
                   (EAP)", RFC 3748, June 2004.\
\
   [RFC4017]       Stanley, D., Walker, J., and B. Aboba, "Extensible\
                   Authentication Protocol (EAP) Method Requirements for\
                   Wireless LANs", RFC 4017, March 2005.\
\
   [RFC4118]       Yang, L., Zerfos, P., and E. Sadot, "Architecture\
                   Taxonomy for Control and Provisioning of Wireless\
                   Access Points (CAPWAP)", RFC 4118, June 2005.\
\
   [RFC4137]       Vollbrecht, J., Eronen, P., Petroni, N., and Y. Ohba,\
                   "State Machines for Extensible Authentication\
                   Protocol (EAP) Peer and Authenticator", RFC 4137,\
                   August 2005.\
\
   [RFC4181]       Heard, C., Ed., "Guidelines for Authors and Reviewers\
                   of MIB Documents", BCP 111, RFC 4181, September 2005.\
\
   [RFC4188]       Norseth, K. and E. Bell, "Definitions of Managed\
                   Objects for Bridges", RFC 4188, September 2005.\
\
   [RFC4363]       Levi, D. and D. Harrington, "Definitions of Managed\
                   Objects for Bridges with Traffic Classes, Multicast\
                   Filtering, and Virtual LAN Extensions", RFC 4363,\
                   January 2006.\
\
   [TYPE-TUT]      IEEE Standards Association, "Use of the IEEE Assigned\
                   EtherType Field with IEEE Std 802.3, 1998 Edition\
                   Local and Metropolitan Area Networks",\
                   http://standards.ieee.org/regauth/ethertype/\
                   type-tut.html.\
\
\
\
\
\
\
IAB                          Informational                     [Page 11]\
\
RFC 4441               IEEE 802/IETF Relationship             March 2006\
\
\
4.  Acknowledgements\
\
   The authors would like to acknowledge Les Bell, Dan Romascanu, Dave\
   Harrington, Tony Jeffree, Fred Baker, Paul Congdon, Paul Langille,\
   and C. M. Heard for contributions to this document.\
\
\
\
\
\
\
\
\
\
\
\
\
\
\
\
\
\
\
\
\
\
\
\
\
\
\
\
\
\
\
\
\
\
\
\
\
\
\
\
\
\
\
\
\
\
\
IAB                          Informational                     [Page 12]\
\
RFC 4441               IEEE 802/IETF Relationship             March 2006\
\
\
Appendix A.  Relationship History\
\
A.1.  MIB Development\
\
A.1.1.  Bridge MIB\
\
   The relationship between IETF and IEEE 802 began in the late 1980s\
   with SNMP MIBs developed for the original IEEE 802.1D standard.\
   Because the IEEE specification [IEEE-802.1D] contained only a\
   functional definition of the counters and operations, the IETF's\
   Bridge MIB WG took on the role of defining the Bridge MIB [RFC1493],\
   which was published as an RFC.  Fred Baker and later Keith McCloghrie\
   served as chairs of the Bridge WG.\
\
   The Bridge MIB combined the work of Keith McCloghrie, Eric Decker,\
   and Paul Langille, with spanning tree expertise provided by Anil\
   Rijsinghani.  Mick Seaman (author of 802.1D) and Floyd Backes (who\
   had written the code for Digital Equipment's spanning tree\
   implementation) were the main contacts within IEEE 802.1.  Since\
   Mick, Floyd, Anil, and Paul all worked for Digital Equipment\
   Corporation at the time, much of the coordination between IEEE 802.1\
   and the Bridge MIB WG took place in the hallways at Digital, rather\
   than within official channels.\
\
A.1.2.  MAU and Hub MIBs\
\
   In the early 1990s when IEEE 802.3 was completing the first Ethernet\
   standards, SNMP was not yet the dominant network management protocol.\
   As a result, a 'protocol independent' MIB is included in Clause 30 of\
   the IEEE 802.3 standard [IEEE-802.3], which is updated each time the\
   Ethernet standard is enhanced to support higher speeds.  In parallel,\
   IEEE 802 participants interested in network management were active in\
   the formation of the IETF HUBMIB WG, which took on the task of\
   transforming IEEE 802 definitions into SNMP MIBs documented as\
   Standards Track RFCs.  This included Dan Romascanu, Chair of the IETF\
   HUBMIB WG since 1996.\
\
   The Charter of the HUBMIB WG explicitly mentions that the IEEE 802.3\
   standard is the starting point for the Ethernet MIB, but at the same\
   time reserves the right to deviate from the IEEE model -- either to\
   cover only part of the capabilities offered by the standard or to add\
   MIB objects that are not directly derived from the IEEE model (mostly\
   implemented in software).  If management needs lead to requirements\
   for hardware support, the IETF HUBMIB WG is to provide this input to\
   IEEE 802.3 in a timely manner.\
\
\
\
\
\
\
IAB                          Informational                     [Page 13]\
\
RFC 4441               IEEE 802/IETF Relationship             March 2006\
\
\
   Cooperation between the IETF HUBMIB WG and IEEE 802.3 has continued\
   for more than a decade until today, mostly based on the work of a few\
   editors supported by their companies, who are taking the IEEE\
   standards and mapping them into a management data model and MIBs.\
   Work items include:\
\
   - The Hub MIB [RFC2108], which has gone through three iterations,\
     and is probably ending its evolution, as repeaters are less used\
     in Ethernets.\
   - The MAU MIB, which has been updated each time a new Ethernet speed\
     is developed, with [RFC3636] accommodating 10-Gbps Ethernet.\
   - The Ethernet-like Interfaces MIB was not originally a work item\
     of the HUBMIB WG, but the WG took responsibility for a revision,\
     published as [RFC3635].\
   - The WAN Interface Sublayer MIB [RFC3637] and the Power Ethernet MIB\
     [RFC3621] were developed in IEEE 802.3 and the IETF HUBMIB WG.\
\
   In 2000, an official liaison was established between IEEE 802.3 and\
   the IETF HUBMIB WG, and Dan Romascanu was appointed IETF liaison.\
   The conditions of the liaison agreement allows editors and other\
   participants in the IETF HUBMIB WG access to work-in-progress drafts\
   in IEEE 802.3 on a personal basis, for the purpose of working on MIBs\
   before the release of the standard.  However, the username and\
   password for IEEE 802.3 document access are not for publication on\
   any IETF website or mailing list.\
\
A.1.3.  802.1p/Q MIB\
\
   In 1996 as the 802.1p and 802.1Q [IEEE-802.1Q] standards were being\
   completed, a need was perceived for development of an SNMP MIB, based\
   on the management clauses of those standards.  IEEE 802 management\
   clauses are written in a manner that was independent of any protocol\
   that may be used to implement them.\
\
   At that time, there were a number of proprietary VLAN management MIBs\
   that were both inadequate and difficult to understand.  As a result,\
   there was a need for a more comprehensive, simpler model for VLAN\
   management, along with the priority and multicast filtering\
   management also defined by these standards.\
\
   A small group of participants from the 802.1 WG began working on the\
   problem independently, then combined their work.  The original\
   authors of the Bridge MIB, on which some of the work was based,\
   reviewed the initial work.\
\
\
\
\
\
\
\
IAB                          Informational                     [Page 14]\
\
RFC 4441               IEEE 802/IETF Relationship             March 2006\
\
\
   By the end of 1997, the work was ready for review by a larger\
   audience.  Andrew Smith worked with Keith McCloghrie, chair of the\
   Bridge MIB WG (dormant at the time), to obtain a meeting slot at the\
   March 1998 IETF meeting.  After this, review and development of the\
   MIB continued on the IETF standards track.\
\
   During the development of [RFC2674], there was no official inter-\
   working between the IETF Bridge MIB and IEEE 802.1 groups.\
   Development of this MIB was successful, because the main developers\
   (Andrew Smith and Les Bell) were involved in both the IEEE 802.1 and\
   the IETF Bridge MIB WGs.\
\
A.1.4.  802.3ad and 802.1X MIBs\
\
   As part of the IEEE 802.3ad and IEEE 802.1X standards work, it was\
   decided that it would be better to develop a MIB as part of the\
   standards, rather than wait until an IETF WG was formed, and develop\
   the MIBs separately, so as to avoid a significant time lag in their\
   development.\
\
   As Les Bell was the participant in IEEE 802.3ad and IEEE 802.1 most\
   familiar with SNMP MIB development, he put together the initial MIBs\
   based on the management framework the groups had come up with.\
   Additional assistance was then received for both MIBs from within the\
   IEEE 802.3ad and IEEE 802.1X groups.  Tony Jeffree, editor of both\
   standards, acted as editor of the MIBs as well.\
\
   The problem with IEEE 802 developing these MIBs without IETF\
   involvement was the lack of review.  IEEE 802 members are generally\
   not familiar with MIBs, and very few comments were received as part\
   of the balloting process for either MIB.\
\
   In the case of the IEEE 802.3ad MIB, this meant that basic errors\
   were not discovered until just before publication.  Unfortunately, by\
   then it was too late, and the corrections submitted to the IEEE\
   802.3ad chair and document editor did not get applied to the\
   published version.\
\
   Subsequent to the publication of [IEEE-802.1X], the IEEE 802.1X MIB\
   was reviewed within the Bridge WG, and several syntax errors were\
   found.  These have been corrected in the version of the MIB module\
   that was developed as part of [IEEE-802.1X-2004].  However, while\
   [IEEE-802.1X-MIB] was originally published as a work in progress\
   within the Bridge WG, there was not sufficient interest to complete\
   its publication as an RFC.  As a result, the draft has now expired.\
\
\
\
\
\
\
IAB                          Informational                     [Page 15]\
\
RFC 4441               IEEE 802/IETF Relationship             March 2006\
\
\
A.1.5.  802.1t, 802.1u, 802.1v, and 802.1w MIBs\
\
   802.1t and 802.1u were minor amendments to the 802.1D and 802.1Q\
   standards, requiring some additions to the MIB published in\
   [RFC2674].  802.1v was a new feature extending the VLAN\
   classification schemes of 802.1Q, also requiring extensions to\
   [RFC2674].  802.1w was a new version of Spanning Tree, requiring\
   rewriting of part of [RFC1493].\
\
   When Les Bell took on the role of Chair of the IETF Bridge MIB WG in\
   2001, these issues were raised as new work items and two volunteers\
   were found to become editors of the Internet-Drafts.  A work item was\
   also included to publish the IEEE 802.1X MIB as an Informational RFC.\
\
   This approach worked well for a while, but it then became difficult\
   for the participants, including the editors and the Chair, to sustain\
   a level of interest sufficient to overcome the difficulties\
   introduced by budget cutbacks.  As a result, the drafts have now\
   expired, although there are no significant technical issues\
   outstanding.\
\
A.2.  AAA/EAP\
\
   Since the late 1990s, IEEE 802.1 has been involved in work relating\
   to authentication and authorization [IEEE-802.1X], which led to\
   discovery of issues in several IETF specifications, including\
   [RFC2284] and [RFC2869].  Similarly, IETF participants have uncovered\
   issues in early versions of the RADIUS usage specifications such as\
   [RFC3580], as well as the IEEE 802.1X state machine [Mishra].\
\
   In order to address these issues and ensure synchronization between\
   IEEE 802.1 and the IETF EAP and AAA WGs, a liaison arrangement was\
   utilized during the development of [IEEE-802.1X] and\
   [IEEE-802.1X-2004].\
\
   IEEE 802.11 groups such as IEEE 802.11i and IEEE 802.11F have also\
   become dependent on EAP and AAA work.  This relationship was more\
   challenging since IEEE 802.11 required development of EAP methods and\
   the EAP Key Management Framework, which represented substantial new\
   IETF work, as opposed to the clarifications and updates required by\
   IEEE 802.1.\
\
A.2.1.  IEEE 802.1X\
\
   IEEE 802.1X-2001 [IEEE-802.1X] defined the encapsulation of EAP\
   [RFC2284] over IEEE 802, as well as a state machine for the joint\
   operation of IEEE 802.1X and EAP.\
\
\
\
\
IAB                          Informational                     [Page 16]\
\
RFC 4441               IEEE 802/IETF Relationship             March 2006\
\
\
   During the development of IEEE 802.1X-2001, several problems were\
   discovered in the specification for RADIUS/EAP [RFC2869], and as a\
   result, work was begun on a revision [RFC3579].  In addition,\
   clarifications were required on how RADIUS attributes defined in\
   [RFC2865], [RFC2866], [RFC2867], [RFC2868], [RFC2869], and [RFC3162]\
   would be interpreted by IEEE 802.1X implementations.  To address\
   this, a non-normative RADIUS usage appendix was added to\
   [IEEE-802.1X], and published as [RFC3580].\
\
   Subsequent to the publication of [IEEE-802.1X], a formal analysis of\
   the IEEE 802.1X state machine by the University of Maryland disclosed\
   several security issues [Mishra].  Discussion within IEEE 802.1\
   pointed to lack of clarity in [RFC2284], which resulted from the\
   absence of a specification for the EAP state machine specification.\
\
   At that time, EAP was handled within the IETF PPPEXT WG, which was\
   largely inactive.  In order to undertake work on a revised EAP\
   specification as well as the specification of the EAP state machine,\
   the IETF EAP WG was formed in July 2002.  Bernard Aboba, a\
   participant in IEEE 802.1 as well as PPPEXT, was named co-chair.\
\
   Work on the EAP state machine [RFC4137] and revised EAP specification\
   [RFC3748] proceeded in parallel within the EAP WG, with issues or\
   changes in one document requiring changes to the other document, as\
   well as revisions to [IEEE-802.1X-2004].  The revised RADIUS/EAP\
   specification [RFC3579] was also reviewed within the EAP WG, since at\
   that time the RADEXT WG had not yet been formed.\
\
   The revision to IEEE 802.1X [IEEE-802.1X-2004] included the\
   following:\
\
   - a revised RADIUS usage appendix based on [RFC3580]\
   - clarifications based on [RFC3579]\
   - a revised IEEE 802.1X state machine, based on [RFC3748] and\
     [RFC4137]\
\
   Due to the deep dependencies between [IEEE-802.1X-2004], [RFC3748],\
   and [RFC4137], a liaison was established between IEEE 802.1X-REV and\
   the IETF EAP WG in August 2002.  This enabled participants in the\
   IETF EAP WG to obtain access to the IEEE 802.1X revision in progress.\
\
   IEEE 802 groups are duty bound to consider all comments received,\
   regardless of their origin.  This allows IETF participants to comment\
   as part of the IEEE 802 ballot process, regardless of their voting\
   status within IEEE 802.  Where there is active cooperation, IETF WGs\
   may be made aware that IEEE 802 ballots are occurring and that their\
\
\
\
\
\
IAB                          Informational                     [Page 17]\
\
RFC 4441               IEEE 802/IETF Relationship             March 2006\
\
\
   comments are welcome.  IEEE 802.1X-REV and IEEE 802.11i ballots were\
   announced on the EAP WG mailing list, as are IEEE 802 interim meeting\
   arrangements.\
\
   Similarly, during the IEEE 802.1X-REV ballot process, comments were\
   received relating to [RFC3748], [RFC4137], and [RFC3579].  These\
   comments were tracked on the EAP WG Issues List, and were\
   subsequently addressed in the documents.\
\
   In April 2003, [RFC3580] was approved by the IESG for publication as\
   an RFC, and in May 2003, [RFC3579] was approved for publication as an\
   RFC.  The review process for both drafts involved bringing the\
   documents to IETF last call, and then reposting the IETF last-call\
   announcement on the IEEE 802.1 mailing list.  While ballot comments\
   on IEEE 802.1X-REV were also reflected in changes to both documents,\
   it was necessary for both documents to be approved for publication as\
   RFCs well in advance of Sponsor Ballot, in order to ensure that RFC\
   numbers would be assigned in time, so as to avoid delaying\
   publication.\
\
   Overall, despite the complex inter-dependencies between\
   [IEEE-802.1X-2004], [RFC3748], and [RFC4137], the documents were\
   produced without undue delay.  This was largely due to the work of\
   joint participants in IEEE 802.1 and IETF EAP WG.\
\
A.2.2.  IEEE 802.11i\
\
   IEEE 802.11i was chartered to specify security enhancements to\
   [IEEE-802.11].  Since [IEEE-802.11i] utilized IEEE 802.1X, it\
   depended on [IEEE-802.1X-2004].  As a result, IEEE 802.11i and IEEE\
   802.1 held joint meetings at IEEE 802 plenaries and established a\
   liaison arrangement that permitted members of either group (as well\
   as EAP WG participants) access to IEEE 802.11i work-in-progress.\
\
   Since [IEEE-802.11i] depended on [IEEE-802.1X-2004], it inherited the\
   dependencies of [IEEE-802.1X-2004], including work on EAP, EAP\
   methods, and AAA support for EAP.  In addition, since IEEE 802.11i\
   utilized EAP for key management whereas [IEEE-802.1X] does not,\
   additional security requirements arose with respect to EAP methods.\
\
   In February 2002, IEEE 802.11 sent a liaison letter to the IESG\
   [IEEE-80211Liaison1] requesting additional work on EAP, EAP methods,\
   and EAP key management.  This letter was presented at the second EAP\
   BOF at IETF 53, and was used as input to the EAP WG charter.  In\
   March 2003, another liaison letter was presented, providing further\
   clarifications on requirements for EAP method work\
   [IEEE-80211Liaison2].  This included a request from IEEE 802.11i for\
\
\
\
\
IAB                          Informational                     [Page 18]\
\
RFC 4441               IEEE 802/IETF Relationship             March 2006\
\
\
   the EAP WG to consider changing the mandatory-to-implement EAP method\
   within [RFC3748], so as to provide a method meeting the security\
   requirements of IEEE 802.11i.\
\
   During IETF 56, the request for changing the mandatory-to-implement\
   method was considered by the EAP WG.  A recommendation was made by\
   the Internet Area Director Erik Nordmark that the IEEE 802.11i\
   requirements be documented in an RFC and that the EAP WG consider the\
   security requirements for EAP methods in various situations.  It was\
   recommended not to change the mandatory-to-implement method, since\
   the EAP WG was not chartered to do work on methods.  However, it was\
   decided to produce a document describing the EAP method requirements\
   for WLAN usage.  This document was subsequently published as\
   [RFC4017].\
\
   Most recently, IEEE 802.11r has been involved in discussions relating\
   to fast handoff, which may potentially require AAA extensions as well\
   as changes to the EAP key hierarchy.  However, the direction of this\
   work has not yet been determined so that no liaison request has been\
   formulated yet.\
\
   In April 2003, Dorothy Stanley was appointed liaison from IEEE 802.11\
   to the IETF, in order to help coordinate between IEEE 802.11 and IETF\
   WGs, including AAA, BMWG, CAPWAP, and EAP.\
\
A.2.3.  IEEE 802.11F\
\
   IEEE 802.11F was chartered with development of a recommended practice\
   for Inter-Access Point Communications.  As part of development of an\
   Inter-Access Point Protocol (IAPP), it was necessary to secure\
   communications between the access points, as well as to support the\
   reverse resolution of the MAC address of the previous access point to\
   its IP address, so as to allow the two access points to communicate\
   via IAPP.  Since the two access points might not be on the same link,\
   Inverse ARP [RFC2390] was not considered sufficient in all cases.\
\
   IEEE 802.11F elected to extend the RADIUS protocol [RFC2865] to\
   provide inverse address resolution as well as IPsec key management.\
   This was accomplished via use of Vendor-Specific Attributes (VSAs),\
   as well as new RADIUS commands, added through definition of\
   additional values for the RADIUS Service-Type attribute.  As a\
   result, IETF review was not required under the IANA considerations\
   included in [RFC2865].  Subsequently, the RADIUS IANA considerations\
   [RFC3575] were revised so as to require IETF review in most cases.\
\
\
\
\
\
\
\
IAB                          Informational                     [Page 19]\
\
RFC 4441               IEEE 802/IETF Relationship             March 2006\
\
\
   No liaison arrangement was developed between IEEE 802.11F and IETF\
   WGs such as AAA WG or SEAMOBY WG, so as to allow IETF participants\
   access to the IEEE 802.11F specifications prior to publication.  Once\
   IEEE 802.11F entered into Recirculation ballot, only comments\
   relating to changes in the specification could be considered.  As a\
   result, issues raised relating to the IEEE 802.11F RADIUS extensions\
   were rejected.\
\
   IEEE 802.11F was a Trial Use Recommended Practice.  The IEEE 802\
   Executive Committee approved its withdrawal on November 18, 2005.  As\
   a result, the RADIUS parameters allocated for use by IEEE 802.11F are\
   available to be reclaimed.\
\
\
\
\
\
\
\
\
\
\
\
\
\
\
\
\
\
\
\
\
\
\
\
\
\
\
\
\
\
\
\
\
\
\
\
\
\
\
\
IAB                          Informational                     [Page 20]\
\
RFC 4441               IEEE 802/IETF Relationship             March 2006\
\
\
Appendix B.  IAB Members at the Time of This Writing\
\
   Bernard Aboba\
   Loa Andersson\
   Brian Carpenter\
   Leslie Daigle\
   Patrik Falstrom\
   Bob Hinden\
   Kurtis Lindqvist\
   David Meyer\
   Pekka Nikander\
   Eric Rescorla\
   Pete Resnick\
   Jonathan Rosenberg\
   Lixia Zhang\
\
Author's Address\
\
   Bernard Aboba\
   Microsoft\
   One Microsoft Way\
   Redmond, WA  98052\
   USA\
\
   EMail: bernarda@microsoft.com\
\
\
\
\
\
\
\
\
\
\
\
\
\
\
\
\
\
\
\
\
\
\
\
\
\
\
IAB                          Informational                     [Page 21]\
\
RFC 4441               IEEE 802/IETF Relationship             March 2006\
\
\
Full Copyright Statement\
\
   Copyright (C) The Internet Society (2006).\
\
   This document is subject to the rights, licenses and restrictions\
   contained in BCP 78, and except as set forth therein, the authors\
   retain all their rights.\
\
   This document and the information contained herein are provided on an\
   "AS IS" basis and THE CONTRIBUTOR, THE ORGANIZATION HE/SHE REPRESENTS\
   OR IS SPONSORED BY (IF ANY), THE INTERNET SOCIETY AND THE INTERNET\
   ENGINEERING TASK FORCE DISCLAIM ALL WARRANTIES, EXPRESS OR IMPLIED,\
   INCLUDING BUT NOT LIMITED TO ANY WARRANTY THAT THE USE OF THE\
   INFORMATION HEREIN WILL NOT INFRINGE ANY RIGHTS OR ANY IMPLIED\
   WARRANTIES OF MERCHANTABILITY OR FITNESS FOR A PARTICULAR PURPOSE.\
\
Intellectual Property\
\
   The IETF takes no position regarding the validity or scope of any\
   Intellectual Property Rights or other rights that might be claimed to\
   pertain to the implementation or use of the technology described in\
   this document or the extent to which any license under such rights\
   might or might not be available; nor does it represent that it has\
   made any independent effort to identify any such rights.  Information\
   on the procedures with respect to rights in RFC documents can be\
   found in BCP 78 and BCP 79.\
\
   Copies of IPR disclosures made to the IETF Secretariat and any\
   assurances of licenses to be made available, or the result of an\
   attempt made to obtain a general license or permission for the use of\
   such proprietary rights by implementers or users of this\
   specification can be obtained from the IETF on-line IPR repository at\
   http://www.ietf.org/ipr.\
\
   The IETF invites any interested party to bring to its attention any\
   copyrights, patents or patent applications, or other proprietary\
   rights that may cover technology that may be required to implement\
   this standard.  Please address the information to the IETF at\
   ietf-ipr@ietf.org.\
\
Acknowledgement\
\
   Funding for the RFC Editor function is provided by the IETF\
   Administrative Support Activity (IASA).\
\
\
\
\
\
\
\
IAB                          Informational                     [Page 22]\
\

doc 3
  field 0
    name titolo
    type string
    value rfc4448.txt
  field 1
    name contenuto
    type string
    value \
\
\
\
\
\
Network Working Group                                    L. Martini, Ed.\
Request for Comments: 4448                                      E. Rosen\
Category: Standards Track                            Cisco Systems, Inc.\
                                                             N. El-Aawar\
                                             Level 3 Communications, LLC\
                                                                G. Heron\
                                                                 Tellabs\
                                                              April 2006\
\
\
   Encapsulation Methods for Transport of Ethernet over MPLS Networks\
\
Status of This Memo\
\
   This document specifies an Internet standards track protocol for the\
   Internet community, and requests discussion and suggestions for\
   improvements.  Please refer to the current edition of the "Internet\
   Official Protocol Standards" (STD 1) for the standardization state\
   and status of this protocol.  Distribution of this memo is unlimited.\
\
Copyright Notice\
\
   Copyright (C) The Internet Society (2006).\
\
Abstract\
\
   An Ethernet pseudowire (PW) is used to carry Ethernet/802.3 Protocol\
   Data Units (PDUs) over an MPLS network.  This enables service\
   providers to offer "emulated" Ethernet services over existing MPLS\
   networks.  This document specifies the encapsulation of\
   Ethernet/802.3 PDUs within a pseudowire.  It also specifies the\
   procedures for using a PW to provide a "point-to-point Ethernet"\
   service.\
\
\
\
\
\
\
\
\
\
\
\
\
\
\
\
\
\
\
Martini, et al.             Standards Track                     [Page 1]\
\
RFC 4448          Encapsulation of Ethernet over MPLS         April 2006\
\
\
Table of Contents\
\
   1. Introduction ....................................................3\
   2. Specification of Requirements ...................................6\
   3. Applicability Statement .........................................6\
   4. Details Specific to Particular Emulated Services ................7\
      4.1. Ethernet Tagged Mode .......................................7\
      4.2. Ethernet Raw Mode ..........................................8\
      4.3. Ethernet-Specific Interface Parameter LDP Sub-TLV ..........8\
      4.4. Generic Procedures .........................................9\
           4.4.1. Raw Mode vs. Tagged Mode ............................9\
           4.4.2. MTU Management on the PE/CE Links ..................11\
           4.4.3. Frame Ordering .....................................11\
           4.4.4. Frame Error Processing .............................11\
           4.4.5. IEEE 802.3x Flow Control Interworking ..............11\
      4.5. Management ................................................12\
      4.6. The Control Word ..........................................12\
      4.7. QoS Considerations ........................................13\
   5. Security Considerations ........................................14\
   6. PSN MTU Requirements ...........................................14\
   7. Normative References ...........................................15\
   8. Informative References .........................................15\
   9. Significant Contributors .......................................17\
   Appendix A. Interoperability Guidelines ...........................20\
      A.1. Configuration Options .....................................20\
      A.2. IEEE 802.3x Flow Control Considerations ...................21\
   Appendix B. QoS Details ...........................................21\
      B.1. Adaptation of 802.1Q CoS to PSN CoS .......................22\
      B.2. Drop Precedence ...........................................23\
\
\
\
\
\
\
\
\
\
\
\
\
\
\
\
\
\
\
\
\
\
\
Martini, et al.             Standards Track                     [Page 2]\
\
RFC 4448          Encapsulation of Ethernet over MPLS         April 2006\
\
\
1.  Introduction\
\
   An Ethernet pseudowire (PW) allows Ethernet/802.3 [802.3] Protocol\
   Data Units (PDUs) to be carried over a Multi-Protocol Label Switched\
   [MPLS-ARCH] network.  In addressing the issues associated with\
   carrying an Ethernet PDU over a packet switched network (PSN), this\
   document assumes that a pseudowire (PW) has been set up by using a\
   control protocol such as the one as described in [PWE3-CTRL].  The\
   design of Ethernet pseudowire described in this document conforms to\
   the pseudowire architecture described in [RFC3985].  It is also\
   assumed in the remainder of this document that the reader is familiar\
   with RFC 3985.\
\
   The Pseudowire Emulation Edge-to-Edge (PWE3) Ethernet PDU consists of\
   the Destination Address, Source Address, Length/Type, MAC Client\
   Data, and padding extracted from a MAC frame as a concatenated octet\
   sequence in their original order [PDU].\
\
   In addition to the Ethernet PDU format used within the pseudowire,\
   this document discusses:\
\
      - Procedures for using a PW in order to provide a pair of Customer\
        Edge (CE) routers with an emulated (point-to-point) Ethernet\
        service, including the procedures for the processing of Provider\
        Edge (PE)-bound and CE-bound Ethernet PDUs [RFC3985]\
\
      - Ethernet-specific quality of service (QoS) and security\
        considerations\
\
      - Inter-domain transport considerations for Ethernet PW\
\
   The following two figures describe the reference models that are\
   derived from [RFC3985] to support the Ethernet PW emulated services.\
\
\
\
\
\
\
\
\
\
\
\
\
\
\
\
\
\
\
Martini, et al.             Standards Track                     [Page 3]\
\
RFC 4448          Encapsulation of Ethernet over MPLS         April 2006\
\
\
            |<-------------- Emulated Service ---------------->|\
            |                                                  |\
            |          |<------- Pseudowire ------->|          |\
            |          |                            |          |\
            |          |    |<-- PSN Tunnel -->|    |          |\
            | PW End   V    V                  V    V  PW End  |\
            V Service  +----+                  +----+  Service V\
      +-----+    |     | PE1|==================| PE2|     |    +-----+\
      |     |----------|............PW1.............|----------|     |\
      | CE1 |    |     |    |                  |    |     |    | CE2 |\
      |     |----------|............PW2.............|----------|     |\
      +-----+  ^ |     |    |==================|    |     | ^  +-----+\
            ^  |       +----+                  +----+     | |  ^\
            |  |   Provider Edge 1         Provider Edge 2  |  |\
            |  |                                            |  |\
      Customer |                                            | Customer\
      Edge 1   |                                            | Edge 2\
               |                                            |\
               |                                            |\
      Attachment Circuit (AC)                    Attachment Circuit (AC)\
      native Ethernet service                    native Ethernet service\
\
         Figure 1: PWE3 Ethernet/VLAN Interface Reference Configuration\
\
   The "emulated service" shown in Figure 1 is, strictly speaking, a\
   bridged LAN; the PEs have MAC interfaces, consume MAC control frames,\
   etc.  However, the procedures specified herein only support the case\
   in which there are two CEs on the "emulated LAN".  Hence we refer to\
   this service as "emulated point-to-point Ethernet".  Specification of\
   the procedures for using pseudowires to emulate LANs with more than\
   two CEs are out of the scope of the current document.\
\
   +-------------+                                +-------------+\
   |  Emulated   |                                |  Emulated   |\
   |  Ethernet   |                                |  Ethernet   |\
   | (including  |         Emulated Service       | (including  |\
   |  VLAN)      |<==============================>|  VLAN)      |\
   |  Services   |                                |  Services   |\
   +-------------+           Pseudowire           +-------------+\
   |Demultiplexer|<==============================>|Demultiplexer|\
   +-------------+                                +-------------+\
   |    PSN      |            PSN Tunnel          |    PSN      |\
   |   MPLS      |<==============================>|   MPLS      |\
   +-------------+                                +-------------+\
   |  Physical   |                                |  Physical   |\
   +-----+-------+                                +-----+-------+\
\
         Figure 2: Ethernet PWE3 Protocol Stack Reference Model\
\
\
\
Martini, et al.             Standards Track                     [Page 4]\
\
RFC 4448          Encapsulation of Ethernet over MPLS         April 2006\
\
\
   For the purpose of this document, PE1 will be defined as the ingress\
   router, and PE2 as the egress router.  A layer 2 PDU will be received\
   at PE1, encapsulated at PE1, transported, decapsulated at PE2, and\
   transmitted out on the attachment circuit of PE2.\
\
   An Ethernet PW emulates a single Ethernet link between exactly two\
   endpoints.  The mechanisms described in this document are agnostic to\
   that which is beneath the "Pseudowire" level in Figure 2, concerning\
   itself only with the "Emulated Service" portion of the stack.\
\
   The following reference model describes the termination point of each\
   end of the PW within the PE:\
\
           +-----------------------------------+\
           |                PE                 |\
   +---+   +-+  +-----+  +------+  +------+  +-+\
   |   |   |P|  |     |  |PW ter|  | PSN  |  |P|\
   |   |<==|h|<=| NSP |<=|minati|<=|Tunnel|<=|h|<== From PSN\
   |   |   |y|  |     |  |on    |  |      |  |y|\
   | C |   +-+  +-----+  +------+  +------+  +-+\
   | E |   |                                   |\
   |   |   +-+  +-----+  +------+  +------+  +-+\
   |   |   |P|  |     |  |PW ter|  | PSN  |  |P|\
   |   |==>|h|=>| NSP |=>|minati|=>|Tunnel|=>|h|==> To PSN\
   |   |   |y|  |     |  |on    |  |      |  |y|\
   +---+   +-+  +-----+  +------+  +------+  +-+\
           |                                   |\
           +-----------------------------------+\
                       ^         ^         ^\
                       |         |         |\
                       A         B         C\
\
           Figure 3: PW Reference Diagram\
\
   The PW terminates at a logical port within the PE, defined at point B\
   in the above diagram.  This port provides an Ethernet MAC service\
   that will deliver each Ethernet frame that is received at point A,\
   unaltered, to the point A in the corresponding PE at the other end of\
   the PW.\
\
   The Native Service Processing (NSP) function includes frame\
   processing that is required for the Ethernet frames that are\
   forwarded to the PW termination point.  Such functions may include\
   stripping, overwriting or adding VLAN tags, physical port\
   multiplexing and demultiplexing, PW-PW bridging, L2 encapsulation,\
   shaping, policing, etc.  These functions are specific to the Ethernet\
   technology, and may not be required for the PW emulation service.\
\
\
\
\
Martini, et al.             Standards Track                     [Page 5]\
\
RFC 4448          Encapsulation of Ethernet over MPLS         April 2006\
\
\
   The points to the left of A, including the physical layer between the\
   CE and PE, and any adaptation (NSP) functions between it and the PW\
   terminations, are outside of the scope of PWE3 and are not defined\
   here.\
\
   "PW Termination", between A and B, represents the operations for\
   setting up and maintaining the PW, and for encapsulating and\
   decapsulating the Ethernet frames as necessary to transmit them\
   across the MPLS network.\
\
   An Ethernet PW operates in one of two modes: "raw mode" or "tagged\
   mode".  In tagged mode, each frame MUST contain at least one 802.1Q\
   [802.1Q] VLAN tag, and the tag value is meaningful to the NSPs at the\
   two PW termination points.  That is, the two PW termination points\
   must have some agreement (signaled or manually configured) on how to\
   process the tag.  On a raw mode PW, a frame MAY contain an 802.1Q\
   VLAN tag, but if it does, the tag is not meaningful to the NSPs, and\
   passes transparently through them.\
\
   Additional terminology relevant to pseudowires and Layer 2 Virtual\
   Private Networking may be found in [RFC4026].\
\
2.  Specification of Requirements\
\
   The key words "MUST", "MUST NOT", "REQUIRED", "SHALL", "SHALL NOT",\
   "SHOULD", "SHOULD NOT", "RECOMMENDED", "MAY", and "OPTIONAL" in this\
   document are to be interpreted as described in RFC 2119 [RFC2119].\
\
3.  Applicability Statement\
\
   The Ethernet PW emulation allows a service provider to offer a "port\
   to port" Ethernet-based service across an MPLS packet switched\
   network (PSN) while the Ethernet VLAN PW emulation allows an\
   "Ethernet VLAN to VLAN" based service across an MPLS packet switched\
   network (PSN).\
\
   The Ethernet or Ethernet VLAN PW has the following characteristics in\
   relationship to the respective native service:\
\
      - An Ethernet PW connects two Ethernet ACs while an Ethernet VLAN\
        PW connects two Ethernet VLAN ACs, supporting bidirectional\
        transport of variable length Ethernet frames.  The ingress\
        Native Service Processing (NSP) function strips the preamble and\
        frame check sequence (FCS) from the Ethernet frame and\
        transports the frame in its entirety across the PW.  This is\
        done regardless of the presence of the 802.1Q tag in the frame.\
        The egress NSP function receives the Ethernet frame from the PW\
        and regenerates the preamble or FCS before forwarding the frame\
\
\
\
Martini, et al.             Standards Track                     [Page 6]\
\
RFC 4448          Encapsulation of Ethernet over MPLS         April 2006\
\
\
        to the attachment circuit.  Since the FCS is not transported\
        across either Ethernet or Ethernet VLAN PWs, payload integrity\
        transparency may be lost.  The OPTIONAL method described in\
        [FCS] can be used to achieve payload integrity transparency on\
        Ethernet or Ethernet VLAN PWs.\
\
      - For an Ethernet VLAN PW, VLAN tag rewrite can be achieved by NSP\
        at the egress PE, which is outside the scope of this document.\
\
      - The Ethernet or Ethernet VLAN PW only supports homogeneous\
        Ethernet frame type across the PW; both ends of the PW must be\
        either tagged or untagged.  Heterogeneous frame type support\
        achieved with NSP functionality is outside the scope of this\
        document.\
\
      - Ethernet port or Ethernet VLAN status notification is provided\
        using the PW Status TLV in the Label Distribution Protocol (LDP)\
        status notification message.  Loss of connectivity between PEs\
        can be detected by the LDP session closing, or by using [VCCV]\
        mechanisms.  The PE can convey these indications back to its\
        attached Remote System.\
\
      - The maximum frame size that can be supported is limited by the\
        PSN MTU minus the MPLS header size, unless fragmentation and\
        reassembly are used [FRAG].\
\
      - The packet switched network may reorder, duplicate, or silently\
        drop packets.  Sequencing MAY be enabled in the Ethernet or\
        Ethernet VLAN PW to detect lost, duplicate, or out-of-order\
        packets on a per-PW basis.\
\
      - The faithfulness of an Ethernet or Ethernet VLAN PW may be\
        increased by leveraging Quality of Service features of the PEs\
        and the underlying PSN.  (See Section 4.7, "QoS\
        Considerations".)\
\
4.  Details Specific to Particular Emulated Services\
\
4.1.  Ethernet Tagged Mode\
\
   The Ethernet frame will be encapsulated according to the procedures\
   defined later in this document for tagged mode.  It should be noted\
   that if the VLAN identifier is modified by the egress PE, the\
   Ethernet spanning tree protocol might fail to work properly.  If this\
   issue is of significance, the VLAN identifier MUST be selected in\
   such a way that it matches on the attachment circuits at both ends of\
   the PW.\
\
\
\
\
Martini, et al.             Standards Track                     [Page 7]\
\
RFC 4448          Encapsulation of Ethernet over MPLS         April 2006\
\
\
   If the PE detects a failure on the Ethernet physical port, or the\
   port is administratively disabled, it MUST send a PW status\
   notification message for all PWs associated with the port.\
\
   This mode uses service-delimiting tags to map input Ethernet frames\
   to respective PWs and corresponds to PW type 0x0004 "Ethernet Tagged\
   Mode" [IANA].\
\
4.2.  Ethernet Raw Mode\
\
   The Ethernet frame will be encapsulated according to the procedures\
   defined later in this document for raw mode.  If the PE detects a\
   failure on the Ethernet input port, or the port is administratively\
   disabled, the PE MUST send an appropriate PW status notification\
   message to the corresponding remote PE.\
\
   In this mode, all Ethernet frames received on the attachment circuit\
   of PE1 will be transmitted to PE2 on a single PW.  This service\
   corresponds to PW type 0x0005 "Ethernet" [IANA].\
\
4.3.  Ethernet-Specific Interface Parameter LDP Sub-TLV\
\
   This LDP sub-Type Length Value [LDP] specifies interface-specific\
   parameters.  When applicable, it MUST be used to validate that the\
   PEs, and the ingress and egress ports at the edges of the circuit,\
   have the necessary capabilities to interoperate with each other.  The\
   Interface parameter TLV is defined in [PWE3-CTRL], the IANA registry\
   with initial values for interface parameter sub-TLV types is defined\
   in [IANA], but the Ethernet-specific interface parameters are\
   specified as follows:\
\
      - 0x06 Requested VLAN ID Sub-TLV\
\
        An Optional 16-bit value indicating the requested VLAN ID.  This\
        parameter MUST be used by a PE that is incapable of rewriting\
        the 802.1Q Ethernet VLAN tag on output.  If the ingress PE\
        receives this request, it MUST rewrite the VLAN ID contained\
        inside the VLAN Tag at the input to match the requested VLAN ID.\
        If this is not possible, and the VLAN ID does not already match\
        the configured ingress VLAN ID, the PW MUST not be enabled.\
        This parameter is applicable only to PW type 0x0004.\
\
\
\
\
\
\
\
\
\
\
Martini, et al.             Standards Track                     [Page 8]\
\
RFC 4448          Encapsulation of Ethernet over MPLS         April 2006\
\
\
4.4.  Generic Procedures\
\
   When the NSP/Forwarder hands a frame to the PW termination function:\
\
      - The preamble (if any) and FCS are stripped off.\
\
      - The control word as defined in Section 4.6, "The Control Word",\
        is, if necessary, prepended to the resulting frame.  The\
        conditions under which the control word is or is not used are\
        specified below.\
\
      - The proper pseudowire demultiplexer (PW Label) is prepended to\
        the resulting packet.\
\
      - The proper tunnel encapsulation is prepended to the resulting\
        packet.\
\
      - The packet is transmitted.\
\
   The way in which the proper tunnel encapsulation and pseudowire\
   demultiplexer is chosen depends on the procedures that were used to\
   set up the pseudowire.\
\
   The tunnel encapsulation depends on how the MPLS PSN is set up.  This\
   can include no label, one label, or multiple labels.  The proper\
   pseudowire demultiplexer is an MPLS label whose value is determined\
   by the PW setup and maintenance protocols.\
\
   When a packet arrives over a PW, the tunnel encapsulation and PW\
   demultiplexer are stripped off.  If the control word is present, it\
   is processed and stripped off.  The resulting frame is then handed to\
   the Forwarder/NSP.  Regeneration of the FCS is considered to be an\
   NSP responsibility.\
\
4.4.1.  Raw Mode vs. Tagged Mode\
\
   When the PE receives an Ethernet frame, and the frame has a VLAN tag,\
   we can distinguish two cases:\
\
      1. The tag is service-delimiting.  This means that the tag was\
         placed on the frame by some piece of service provider-operated\
         equipment, and the tag is used by the service provider to\
         distinguish the traffic.  For example, LANs from different\
         customers might be attached to the same service provider\
         switch, which applies VLAN tags to distinguish one customer's\
         traffic from another's, and then forwards the frames to the PE.\
\
\
\
\
\
Martini, et al.             Standards Track                     [Page 9]\
\
RFC 4448          Encapsulation of Ethernet over MPLS         April 2006\
\
\
      2. The tag is not service-delimiting.  This means that the tag was\
         placed in the frame by a piece of customer equipment, and is\
         not meaningful to the PE.\
\
   Whether or not the tag is service-delimiting is determined by local\
   configuration on the PE.\
\
   If an Ethernet PW is operating in raw mode, service-delimiting tags\
   are NEVER sent over the PW.  If a service-delimiting tag is present\
   when the frame is received from the attachment circuit by the PE, it\
   MUST be stripped (by the NSP) from the frame before the frame is sent\
   to the PW.\
\
   If an Ethernet PW is operating in tagged mode, every frame sent on\
   the PW MUST have a service-delimiting VLAN tag.  If the frame as\
   received by the PE from the attachment circuit does not have a\
   service-delimiting VLAN tag, the PE must prepend the frame with a\
   dummy VLAN tag before sending the frame on the PW.  This is the\
   default operating mode.  This is the only REQUIRED mode.\
\
   In both modes, non-service-delimiting tags are passed transparently\
   across the PW as part of the payload.  It should be noted that a\
   single Ethernet packet may contain more than one tag.  At most, one\
   of these tags may be service-delimiting.  In any case, the NSP\
   function may only inspect the outermost tag for the purpose of\
   adapting the Ethernet frame to the pseudowire.\
\
   In both modes, the service-delimiting tag values have only local\
   significance, i.e., are meaningful only at a particular PE-CE\
   interface.  When tagged mode is used, the PE that receives a frame\
   from the PW may rewrite the tag value, or may strip the tag entirely,\
   or may leave the tag unchanged, depending on its configuration.  When\
   raw mode is used, the PE that receives a frame may or may not need to\
   add a service-delimiting tag before transmitting the frame on the\
   attachment circuit; however, it MUST not rewrite or remove any tags\
   that are already present.\
\
   The following table illustrates the operations that might be\
   performed at input from the attachment circuit:\
\
   +-----------------------------------------------------------+\
   |       Tag-> |  service delimiting | non service delimiting|\
   |-------------+---------------------+-----------------------|\
   |   Raw Mode  | 1st VLAN Tag Removed| no operation performed|\
   |-------------+---------------------+-----------------------|\
   | Tagged Mode | NO OP or Tag Added  |     Tag Added         |\
   +-----------------------------------------------------------+\
\
\
\
\
Martini, et al.             Standards Track                    [Page 10]\
\
RFC 4448          Encapsulation of Ethernet over MPLS         April 2006\
\
\
4.4.2.  MTU Management on the PE/CE Links\
\
   The Ethernet PW MUST NOT be enabled unless it is known that the MTUs\
   of the CE-PE links are the same at both ends of the PW.  If an egress\
   router receives an encapsulated layer 2 PDU whose payload length\
   (i.e., the length of the PDU itself without any of the encapsulation\
   headers) exceeds the MTU of the destination layer 2 interface, the\
   PDU MUST be dropped.\
\
4.4.3.  Frame Ordering\
\
   In general, applications running over Ethernet do not require strict\
   frame ordering.  However, the IEEE definition of 802.3 [802.3]\
   requires that frames from the same conversation in the context of\
   link aggregation (clause 43) are delivered in sequence.  Moreover,\
   the PSN cannot (in the general case) be assumed to provide or to\
   guarantee frame ordering.  An Ethernet PW can, through use of the\
   control word, provide strict frame ordering.  If this option is\
   enabled, any frames that get misordered by the PSN will be dropped or\
   reordered by the receiving PW endpoint.  If strict frame ordering is\
   a requirement for a particular PW, this option MUST be enabled.\
\
4.4.4.  Frame Error Processing\
\
   An encapsulated Ethernet frame traversing a pseudowire may be\
   dropped, corrupted, or delivered out-of-order.  As described in\
   [PWE3-REQ], frame loss, corruption, and out-of-order delivery are\
   considered to be a "generalized bit error" of the pseudowire.  PW\
   frames that are corrupted will be detected at the PSN layer and\
   dropped.\
\
   At the ingress of the PW, the native Ethernet frame error processing\
   mechanisms MUST be enabled.  Therefore, if a PE device receives an\
   Ethernet frame containing hardware-level Cyclic Redundancy Check\
   (CRC) errors, framing errors, or a runt condition, the frame MUST be\
   discarded on input.  Note that defining this processing is part of\
   the NSP function and is outside the scope of this document.\
\
4.4.5.  IEEE 802.3x Flow Control Interworking\
\
   In a standard Ethernet network, the flow control mechanism is\
   optional and typically configured between the two nodes on a point-\
   to-point link (e.g., between the CE and the PE).  IEEE 802.3x PAUSE\
   frames MUST NOT be carried across the PW.  See Appendix A for notes\
   on CE-PE flow control.\
\
\
\
\
\
\
Martini, et al.             Standards Track                    [Page 11]\
\
RFC 4448          Encapsulation of Ethernet over MPLS         April 2006\
\
\
4.5.  Management\
\
   The Ethernet PW management model follows the general PW management\
   model defined in [RFC3985] and [PWE3-MIB].  Many common PW management\
   facilities are provided here, with no additional Ethernet specifics\
   necessary.  Ethernet-specific parameters are defined in an additional\
   MIB module, [PW-MIB].\
\
4.6.  The Control Word\
\
   The control word defined in this section is based on the Generic PW\
   MPLS Control Word as defined in [PWE3-CW].  It provides the ability\
   to sequence individual frames on the PW, avoidance of equal-cost\
   multiple-path load-balancing (ECMP) [RFC2992], and Operations and\
   Management (OAM) mechanisms including VCCV [VCCV].\
\
   [PWE3-CW] states, "If a PW is sensitive to packet misordering and is\
   being carried over an MPLS PSN that uses the contents of the MPLS\
   payload to select the ECMP path, it MUST employ a mechanism which\
   prevents packet misordering." This is necessary because ECMP\
   implementations may examine the first nibble after the MPLS label\
   stack to determine whether the labelled packet is IP or not.  Thus,\
   if the source MAC address of an Ethernet frame carried over the PW\
   without a control word present begins with 0x4 or 0x6, it could be\
   mistaken for an IPv4 or IPv6 packet.  This could, depending on the\
   configuration and topology of the MPLS network, lead to a situation\
   where all packets for a given PW do not follow the same path.  This\
   may increase out-of-order frames on a given PW, or cause OAM packets\
   to follow a different path than actual traffic (see Section 4.4.3,\
   "Frame Ordering").\
\
   The features that the control word provides may not be needed for a\
   given Ethernet PW.  For example, ECMP may not be present or active on\
   a given MPLS network, strict frame sequencing may not be required,\
   etc.  If this is the case, the control word provides little value and\
   is therefore optional.  Early Ethernet PW implementations have been\
   deployed that do not include a control word or the ability to process\
   one if present.  To aid in backwards compatibility, future\
   implementations MUST be able to send and receive frames without the\
   control word present.\
\
   In all cases, the egress PE MUST be aware of whether the ingress PE\
   will send a control word over a specific PW.  This may be achieved by\
   configuration of the PEs, or by signaling, as defined in [PWE3-CTRL].\
\
\
\
\
\
\
\
Martini, et al.             Standards Track                    [Page 12]\
\
RFC 4448          Encapsulation of Ethernet over MPLS         April 2006\
\
\
   The control word is defined as follows:\
\
    0                   1                   2                   3\
    0 1 2 3 4 5 6 7 8 9 0 1 2 3 4 5 6 7 8 9 0 1 2 3 4 5 6 7 8 9 0 1\
   +-+-+-+-+-+-+-+-+-+-+-+-+-+-+-+-+-+-+-+-+-+-+-+-+-+-+-+-+-+-+-+-+\
   |0 0 0 0|   Reserved            |       Sequence Number         |\
   +-+-+-+-+-+-+-+-+-+-+-+-+-+-+-+-+-+-+-+-+-+-+-+-+-+-+-+-+-+-+-+-+\
\
   In the above diagram, the first 4 bits MUST be set to 0 to indicate\
   PW data.  The rest of the first 16 bits are reserved for future use.\
   They MUST be set to 0 when transmitting, and MUST be ignored upon\
   receipt.\
\
   The next 16 bits provide a sequence number that can be used to\
   guarantee ordered frame delivery.  The processing of the sequence\
   number field is OPTIONAL.\
\
   The sequence number space is a 16-bit, unsigned circular space.  The\
   sequence number value 0 is used to indicate that the sequence number\
   check algorithm is not used.  The sequence number processing\
   algorithm is found in [PWE3-CW].\
\
4.7.  QoS Considerations\
\
   The ingress PE MAY consider the user priority (PRI) field [802.1Q] of\
   the VLAN tag header when determining the value to be placed in a QoS\
   field of the encapsulating protocol (e.g., the EXP fields of the MPLS\
   label stack).  In a similar way, the egress PE MAY consider the QoS\
   field of the encapsulating protocol (e.g., the EXP fields of the MPLS\
   label stack) when queuing the frame for transmission towards the CE.\
\
   A PE MUST support the ability to carry the Ethernet PW as a best-\
   effort service over the MPLS PSN.  PRI bits are kept transparent\
   between PE devices, regardless of the QoS support of the PSN.\
\
   If an 802.1Q VLAN field is added at the PE, a default PRI setting of\
   zero MUST be supported, a configured default value is recommended, or\
   the value may be mapped from the QoS field of the PSN, as referred to\
   above.\
\
   A PE may support additional QoS support by means of one or more of\
   the following methods:\
\
        i.  One class of service (CoS) per PW End Service (PWES), mapped\
            to a single CoS PW at the PSN.\
       ii.  Multiple CoS per PWES mapped to a single PW with multiple\
            CoS at the PSN.\
      iii.  Multiple CoS per PWES mapped to multiple PWs at the PSN.\
\
\
\
Martini, et al.             Standards Track                    [Page 13]\
\
RFC 4448          Encapsulation of Ethernet over MPLS         April 2006\
\
\
   Examples of the cases above and details of the service mapping\
   considerations are described in Appendix B.\
\
   The PW guaranteed rate at the MPLS PSN level is PW service provider\
   policy based on agreement with the customer, and may be different\
   from the Ethernet physical port rate.\
\
5.  Security Considerations\
\
   The Ethernet pseudowire type is subject to all of the general\
   security considerations discussed in [RFC3985] and [PWE3-CTRL].\
\
   The Ethernet pseudowire is transported on an MPLS PSN; therefore, the\
   security of the pseudowire itself will only be as good as the\
   security of the MPLS PSN.  The MPLS PSN can be secured by various\
   methods, as described in [MPLS-ARCH].\
\
   Security achieved by access control of MAC addresses is out of the\
   scope of this document.  Additional security requirements related to\
   the use of PW in a switching (virtual bridging) environment are not\
   discussed here as they are not within the scope of this document.\
\
6.  PSN MTU Requirements\
\
   The MPLS PSN MUST be configured with an MTU that is large enough to\
   transport a maximum-sized Ethernet frame that has been encapsulated\
   with a control word, a pseudowire demultiplexer, and a tunnel\
   encapsulation.  With MPLS used as the tunneling protocol, for\
   example, this is likely to be 8 or more bytes greater than the\
   largest frame size.  The methodology described in [FRAG] MAY be used\
   to fragment encapsulated frames that exceed the PSN MTU.  However, if\
   [FRAG] is not used and if the ingress router determines that an\
   encapsulated layer 2 PDU exceeds the MTU of the PSN tunnel through\
   which it must be sent, the PDU MUST be dropped.\
\
\
\
\
\
\
\
\
\
\
\
\
\
\
\
\
\
Martini, et al.             Standards Track                    [Page 14]\
\
RFC 4448          Encapsulation of Ethernet over MPLS         April 2006\
\
\
7.  Normative References\
\
   [PWE3-CW]    Bryant, S., Swallow, G., and D. McPherson, "Pseudowire\
                Emulation Edge-to-Edge (PWE3) Control Word for Use over\
                an MPLS PSN", RFC 4385, February 2006.\
\
   [IANA]       Martini, L., "IANA Allocations for Pseudowire Edge to\
                Edge Emulation (PWE3)", BCP 116, RFC 4446, April 2006.\
\
   [PWE3-CTRL]  Martini, L., El-Aawar, N., Heron, G., Rosen, E., Tappan,\
                D., and T. Smith, "Pseudowire Setup and Maintenance\
                using the Label Distribution Protocol (LDP)", RFC 4447,\
                April 2006.\
\
   [MPLS-ARCH]  Rosen, E., Viswanathan, A., and R. Callon,\
                "Multiprotocol Label Switching Architecture", RFC 3031,\
                January 2001.\
\
   [802.3]      IEEE802.3-2005, ISO/IEC 8802-3: 2000 (E), "IEEE Standard\
                for Information technology -- Telecommunications and\
                information exchange between systems -- Local and\
                metropolitan\
                 area networks -- Specific requirements -- Part 3:\
                Carrier Sense Multiple Access with Collision Detection\
                (CSMA/CD) Access Method and Physical Layer\
                Specifications", 2005.\
\
   [802.1Q]     ANSI/IEEE Standard 802.1Q-2005, "IEEE Standards for\
                Local and Metropolitan Area Networks: Virtual Bridged\
                Local Area Networks", 2005.\
\
   [PDU]        IEEE Std 802.3, 1998 Edition, "Part 3: Carrier sense\
                multiple access with collision detection (CSMA/CD)\
                access method and physical layer specifications" figure\
                3.1, 1998\
\
   [RFC2119]    Bradner, S., "Key words for use in RFCs to Indicate\
                Requirement Levels", BCP 14, RFC 2119, March 1997.\
\
8.  Informative References\
\
   [RFC3985]    Bryant, S. and P. Pate, "Pseudo Wire Emulation Edge-to-\
                Edge (PWE3) Architecture", RFC 3985, March 2005.\
\
   [PW-MIB]     Zelig, D. and T. Nadeau, "Ethernet Pseudo Wire (PW)\
                Management Information Base", Work in Progress, February\
                2006.\
\
\
\
\
Martini, et al.             Standards Track                    [Page 15]\
\
RFC 4448          Encapsulation of Ethernet over MPLS         April 2006\
\
\
   [PWE3-REQ]   Xiao, X., McPherson, D., and P. Pate, "Requirements for\
                Pseudo-Wire Emulation Edge-to-Edge (PWE3)", RFC 3916,\
                September 2004.\
\
   [PWE3-MIB]   Zelig, D., Ed. and T. Nadeau, Ed., "Pseudo Wire (PW)\
                Management Information Base", Work in Progress, February\
                2006.\
\
   [LDP]        Andersson, L., Doolan, P., Feldman, N., Fredette, A.,\
                and B. Thomas, "LDP Specification", RFC 3036, January\
                2001.\
\
   [FRAG]       Malis, A. and W. Townsley, "PWE3 Fragmentation and\
                Reassembly", Work in Progress, February 2005.\
\
   [FCS]        Malis, A., Allan, D., and N. Del Regno, "PWE3 Frame\
                Check Sequence Retention", Work in Progress, September\
                2005.\
\
   [VCCV]       Nadeau, T., Ed. and R. Aggarwal, Ed., "Pseudo Wire\
                Virtual Circuit Connectivity Verification (VCCV)", Work\
                in Progress, August 2005.\
\
   [RFC2992]    Hopps, C., "Analysis of an Equal-Cost Multi-Path\
                Algorithm", RFC 2992, November 2000.\
\
   [RFC4026]    Andersson, L. and T. Madsen, "Provider Provisioned\
                Virtual Private Network (VPN) Terminology", RFC 4026,\
                March 2005.\
\
   [L2TPv3]     Lau, J., Townsley, M., and I. Goyret, "Layer Two\
                Tunneling Protocol - Version 3 (L2TPv3)", RFC 3931,\
                March 2005.\
\
\
\
\
\
\
\
\
\
\
\
\
\
\
\
\
\
\
Martini, et al.             Standards Track                    [Page 16]\
\
RFC 4448          Encapsulation of Ethernet over MPLS         April 2006\
\
\
9.  Significant Contributors\
\
   Andrew G. Malis\
   Tellabs\
   90 Rio Robles Dr.\
   San Jose, CA 95134\
\
   EMail: Andy.Malis@tellabs.com\
\
\
   Dan Tappan\
   Cisco Systems, Inc.\
   1414 Massachusetts Avenue\
   Boxborough, MA 01719\
\
   EMail: tappan@cisco.com\
\
\
   Steve Vogelsang\
   ECI Telecom\
   Omega Corporate Center\
   1300 Omega Drive\
   Pittsburgh, PA 15205\
\
   EMail: stephen.vogelsang@ecitele.com\
\
\
   Vinai Sirkay\
   Reliance Infocomm\
   Dhirubai Ambani Knowledge City\
   Navi Mumbai 400 709\
   India\
\
   EMail: vinai@sirkay.com\
\
\
   Vasile Radoaca\
   Nortel Networks\
   600  Technology Park\
   Billerica MA 01821\
\
   EMail: vasile@nortelnetworks.com\
\
\
\
\
\
\
\
\
\
Martini, et al.             Standards Track                    [Page 17]\
\
RFC 4448          Encapsulation of Ethernet over MPLS         April 2006\
\
\
   Chris Liljenstolpe\
   Alcatel\
   11600 Sallie Mae Dr.\
   9th Floor\
   Reston, VA 20193\
\
   EMail: chris.liljenstolpe@alcatel.com\
\
\
   Kireeti Kompella\
   Juniper Networks\
   1194 N. Mathilda Ave\
   Sunnyvale, CA 94089\
\
   EMail: kireeti@juniper.net\
\
\
   Tricci So\
   Nortel Networks 3500 Carling Ave.,\
   Nepean, Ontario,\
   Canada, K2H 8E9.\
\
   EMail: tso@nortelnetworks.com\
\
\
   XiPeng Xiao\
   Riverstone Networks\
   5200 Great America Parkway\
   Santa Clara, CA 95054\
\
   EMail: xxiao@riverstonenet.com\
\
\
   Christopher O.  Flores\
   T-Systems\
   10700 Parkridge Boulevard\
   Reston, VA 20191\
   USA\
\
   EMail: christopher.flores@usa.telekom.de\
\
\
   David Zelig\
   Corrigent Systems\
   126, Yigal Alon St.\
   Tel Aviv, ISRAEL\
\
   EMail: davidz@corrigent.com\
\
\
\
Martini, et al.             Standards Track                    [Page 18]\
\
RFC 4448          Encapsulation of Ethernet over MPLS         April 2006\
\
\
   Raj Sharma\
   Luminous Networks, Inc.\
   10460 Bubb Road\
   Cupertino, CA 95014\
\
   EMail: raj@luminous.com\
\
\
   Nick Tingle\
   TiMetra Networks\
   274 Ferguson Drive\
   Mountain View, CA 94043\
\
   EMail: nick@timetra.com\
\
\
   Sunil Khandekar\
   TiMetra Networks\
   274 Ferguson Drive\
   Mountain View, CA 94043\
\
   EMail: sunil@timetra.com\
\
\
   Loa Andersson\
   TLA-group\
\
   EMail: loa@pi.se\
\
\
\
\
\
\
\
\
\
\
\
\
\
\
\
\
\
\
\
\
\
\
\
Martini, et al.             Standards Track                    [Page 19]\
\
RFC 4448          Encapsulation of Ethernet over MPLS         April 2006\
\
\
Appendix A.  Interoperability Guidelines\
\
A.1.  Configuration Options\
\
   The following is a list of the configuration options for a point-to-\
   point Ethernet PW based on the reference points of Figure 3:\
\
   --------------|---------------|---------------|------------------\
   Service and   |  Encap on C   |Operation at B | Remarks\
   Encap on A    |               |ingress/egress |\
   --------------|---------------|---------------|------------------\
   1) Raw        | Raw - Same as |               |\
                 | A             |               |\
                 |               |               |\
   --------------|---------------|---------------|------------------\
   2) Tag1       | Tag2          |Optional change| VLAN can be\
                 |               |of VLAN value  | 0-4095\
                 |               |               | Change allowed in\
                 |               |               | both directions\
   --------------|---------------|---------------|------------------\
   3) No Tag     | Tag           |Add/remove Tag | Tag can be\
                 |               |field          | 0-4095\
                 |               |               | (note i)\
                 |               |               |\
   --------------|---------------|---------------|------------------\
   4) Tag        | No Tag        |Remove/add Tag | (note ii)\
                 |               |field          |\
                 |               |               |\
                 |               |               |\
   --------------|---------------|---------------|------------------\
\
                      Figure 4: Configuration Options\
\
   Allowed combinations:\
\
   Raw and other services are not allowed on the same NSP virtual port\
   (A).  All other combinations are allowed, except that conflicting\
   VLANs on (A) are not allowed.  Note that in most point-to-point PW\
   applications the NSP virtual port is the same entity as the physical\
   port.\
\
   Notes:\
\
        i.  Mode #3 MAY be limited to adding VLAN NULL only, since\
            change of VLAN or association to specific VLAN can be done\
            at the PW CE-bound side.\
\
\
\
\
\
Martini, et al.             Standards Track                    [Page 20]\
\
RFC 4448          Encapsulation of Ethernet over MPLS         April 2006\
\
\
       ii.  Mode #4 exists in layer 2 switches, but is not recommended\
            when operating with PW since it may not preserve the user's\
            PRI bits.  If there is a need to remove the VLAN tag (for\
            TLS at the other end of the PW), it is recommended to use\
            mode #2 with tag2=0 (NULL VLAN) on the PW and use mode #3 at\
            the other end of the PW.\
\
A.2.  IEEE 802.3x Flow Control Considerations\
\
   If the receiving node becomes congested, it can send a special frame,\
   called the PAUSE frame, to the source node at the opposite end of the\
   connection.  The implementation MUST provide a mechanism for\
   terminating PAUSE frames locally (i.e., at the local PE).  It MUST\
   operate as follows: PAUSE frames received on a local Ethernet port\
   SHOULD cause the PE device to buffer, or to discard, further Ethernet\
   frames for that port until the PAUSE condition is cleared.\
   Optionally, the PE MAY simply discard PAUSE frames.\
\
   If the PE device wishes to pause data received on a local Ethernet\
   port (perhaps because its own buffers are filling up or because it\
   has received notification of congestion within the PSN), then it MAY\
   issue a PAUSE frame on the local Ethernet port, but MUST clear this\
   condition when willing to receive more data.\
\
Appendix B.  QoS Details\
\
   Section 4.7, "QoS Considerations", describes various modes for\
   supporting PW QOS over the PSN.  Examples of the above for a point-\
   to-point VLAN service are:\
\
      - The classification to the PW is based on VLAN field, but the\
        user PRI bits are mapped to different CoS markings (and network\
        behavior) at the PW level.  An example of this is a PW mapped to\
        an E-LSP in an MPLS network.\
\
      - The classification to the PW is based on VLAN field and the PRI\
        bits, and frames with different PRI bits are mapped to different\
        PWs.  An example is to map a PWES to different L-LSPs in MPLS\
        PSN in order to support multiple CoS over an L-LSP-capable\
        network, or to map a PWES to multiple L2TPv3 sessions [L2TPv3].\
\
        The specific value to be assigned at the PSN for various CoS is\
        out of the scope of this document.\
\
\
\
\
\
\
\
\
Martini, et al.             Standards Track                    [Page 21]\
\
RFC 4448          Encapsulation of Ethernet over MPLS         April 2006\
\
\
B.1.  Adaptation of 802.1Q CoS to PSN CoS\
\
   It is not required that the PSN will have the same CoS definition of\
   CoS as defined in [802.1Q], and the mapping of 802.1Q CoS to PSN CoS\
   is application specific and depends on the agreement between the\
   customer and the PW provider.  However, the following principles\
   adopted from 802.1Q, Table 8-2, MUST be met when applying the set of\
   PSN CoS based on user's PRI bits.\
\
                ----------------------------------\
                |#of available classes of service|\
   -------------||---+---+---+---+---+---+---+---|\
   User         || 1 | 2 | 3 | 4 | 5 | 6 | 7 | 8 |\
   Priority     ||   |   |   |   |   |   |   |   |\
   ===============================================\
   0 Best Effort|| 0 | 0 | 0 | 1 | 1 | 1 | 1 | 2 |\
   (Default)    ||   |   |   |   |   |   |   |   |\
   ------------ ||---+---+---+---+---+---+---+---|\
   1 Background || 0 | 0 | 0 | 0 | 0 | 0 | 0 | 0 |\
                ||   |   |   |   |   |   |   |   |\
   ------------ ||---+---+---+---+---+---+---+---|\
   2 Spare      || 0 | 0 | 0 | 0 | 0 | 0 | 0 | 1 |\
                ||   |   |   |   |   |   |   |   |\
   ------------ ||---+---+---+---+---+---+---+---|\
   3 Excellent  || 0 | 0 | 0 | 1 | 1 | 2 | 2 | 3 |\
   Effort       ||   |   |   |   |   |   |   |   |\
   ------------ ||---+---+---+---+---+---+---+---|\
   4 Controlled || 0 | 1 | 1 | 2 | 2 | 3 | 3 | 4 |\
   Load         ||   |   |   |   |   |   |   |   |\
   ------------ ||---+---+---+---+---+---+---+---|\
   5 Interactive|| 0 | 1 | 1 | 2 | 3 | 4 | 4 | 5 |\
   Multimedia   ||   |   |   |   |   |   |   |   |\
   ------------ ||---+---+---+---+---+---+---+---|\
   6 Interactive|| 0 | 1 | 2 | 3 | 4 | 5 | 5 | 6 |\
   Voice        ||   |   |   |   |   |   |   |   |\
   ------------ ||---+---+---+---+---+---+---+---|\
   7 Network    || 0 | 1 | 2 | 3 | 4 | 5 | 6 | 7 |\
   Control      ||   |   |   |   |   |   |   |   |\
   ------------ ||---+---+---+---+---+---+---+---|\
\
                     Figure 5: IEEE 802.1Q CoS Mapping\
\
\
\
\
\
\
\
\
\
\
Martini, et al.             Standards Track                    [Page 22]\
\
RFC 4448          Encapsulation of Ethernet over MPLS         April 2006\
\
\
B.2.  Drop Precedence\
\
   The 802.1P standard does not support drop precedence; therefore, from\
   the PW PE-bound point of view there is no mapping required.  It is,\
   however, possible to mark different drop precedence for different PW\
   frames based on the operator policy and required network behavior.\
   This functionality is not discussed further here.\
\
   PSN QoS support and signaling of QoS are out of the scope of this\
   document.\
\
Authors' Addresses\
\
   Luca Martini, Editor\
   Cisco Systems, Inc.\
   9155 East Nichols Avenue, Suite 400\
   Englewood, CO, 80112\
\
   EMail: lmartini@cisco.com\
\
\
   Nasser El-Aawar\
   Level 3 Communications, LLC.\
   1025 Eldorado Blvd.\
   Broomfield, CO, 80021\
\
   EMail: nna@level3.net\
\
\
   Giles Heron\
   Tellabs\
   Abbey Place\
   24-28 Easton Street\
   High Wycombe\
   Bucks\
   HP11 1NT\
   UK\
\
   EMail: giles.heron@tellabs.com\
\
\
   Eric C. Rosen\
   Cisco Systems, Inc.\
   1414 Massachusetts Avenue\
   Boxborough, MA 01719\
\
   EMail: erosen@cisco.com\
\
\
\
\
Martini, et al.             Standards Track                    [Page 23]\
\
RFC 4448          Encapsulation of Ethernet over MPLS         April 2006\
\
\
Full Copyright Statement\
\
   Copyright (C) The Internet Society (2006).\
\
   This document is subject to the rights, licenses and restrictions\
   contained in BCP 78, and except as set forth therein, the authors\
   retain all their rights.\
\
   This document and the information contained herein are provided on an\
   "AS IS" basis and THE CONTRIBUTOR, THE ORGANIZATION HE/SHE REPRESENTS\
   OR IS SPONSORED BY (IF ANY), THE INTERNET SOCIETY AND THE INTERNET\
   ENGINEERING TASK FORCE DISCLAIM ALL WARRANTIES, EXPRESS OR IMPLIED,\
   INCLUDING BUT NOT LIMITED TO ANY WARRANTY THAT THE USE OF THE\
   INFORMATION HEREIN WILL NOT INFRINGE ANY RIGHTS OR ANY IMPLIED\
   WARRANTIES OF MERCHANTABILITY OR FITNESS FOR A PARTICULAR PURPOSE.\
\
Intellectual Property\
\
   The IETF takes no position regarding the validity or scope of any\
   Intellectual Property Rights or other rights that might be claimed to\
   pertain to the implementation or use of the technology described in\
   this document or the extent to which any license under such rights\
   might or might not be available; nor does it represent that it has\
   made any independent effort to identify any such rights.  Information\
   on the procedures with respect to rights in RFC documents can be\
   found in BCP 78 and BCP 79.\
\
   Copies of IPR disclosures made to the IETF Secretariat and any\
   assurances of licenses to be made available, or the result of an\
   attempt made to obtain a general license or permission for the use of\
   such proprietary rights by implementers or users of this\
   specification can be obtained from the IETF on-line IPR repository at\
   http://www.ietf.org/ipr.\
\
   The IETF invites any interested party to bring to its attention any\
   copyrights, patents or patent applications, or other proprietary\
   rights that may cover technology that may be required to implement\
   this standard.  Please address the information to the IETF at\
   ietf-ipr@ietf.org.\
\
Acknowledgement\
\
   Funding for the RFC Editor function is provided by the IETF\
   Administrative Support Activity (IASA).\
\
\
\
\
\
\
\
Martini, et al.             Standards Track                    [Page 24]\
\

doc 4
  field 0
    name titolo
    type string
    value rfc4443.txt
  field 1
    name contenuto
    type string
    value \
\
\
\
\
\
Network Working Group                                           A. Conta\
Request for Comments: 4443                                    Transwitch\
Obsoletes: 2463                                               S. Deering\
Updates: 2780                                              Cisco Systems\
Category: Standards Track                                  M. Gupta, Ed.\
                                                         Tropos Networks\
                                                              March 2006\
\
\
               Internet Control Message Protocol (ICMPv6)\
        for the Internet Protocol Version 6 (IPv6) Specification\
\
Status of This Memo\
\
   This document specifies an Internet standards track protocol for the\
   Internet community, and requests discussion and suggestions for\
   improvements.  Please refer to the current edition of the "Internet\
   Official Protocol Standards" (STD 1) for the standardization state\
   and status of this protocol.  Distribution of this memo is unlimited.\
\
Copyright Notice\
\
   Copyright (C) The Internet Society (2006).\
\
Abstract\
\
   This document describes the format of a set of control messages used\
   in ICMPv6 (Internet Control Message Protocol).  ICMPv6 is the\
   Internet Control Message Protocol for Internet Protocol version 6\
   (IPv6).\
\
\
\
\
\
\
\
\
\
\
\
\
\
\
\
\
\
\
\
\
\
Conta, et al.               Standards Track                     [Page 1]\
\
RFC 4443                 ICMPv6 (ICMP for IPv6)               March 2006\
\
\
Table of Contents\
\
\
   1. Introduction ....................................................2\
   2. ICMPv6 (ICMP for IPv6) ..........................................3\
      2.1. Message General Format .....................................3\
      2.2. Message Source Address Determination .......................5\
      2.3. Message Checksum Calculation ...............................5\
      2.4. Message Processing Rules ...................................5\
   3. ICMPv6 Error Messages ...........................................8\
      3.1. Destination Unreachable Message ............................8\
      3.2. Packet Too Big Message ....................................10\
      3.3. Time Exceeded Message .....................................11\
      3.4. Parameter Problem Message .................................12\
   4. ICMPv6 Informational Messages ..................................13\
      4.1. Echo Request Message ......................................13\
      4.2. Echo Reply Message ........................................14\
   5. Security Considerations ........................................15\
      5.1. Authentication and Confidentiality of ICMP Messages .......15\
      5.2. ICMP Attacks ..............................................16\
   6. IANA Considerations ............................................17\
      6.1. Procedure for New ICMPV6 Type and Code Value Assignments ..17\
      6.2. Assignments for This Document .............................18\
   7. References .....................................................19\
      7.1. Normative References ......................................19\
      7.2. Informative References ....................................19\
   8. Acknowledgements ...............................................20\
   Appendix A - Changes since RFC 2463................................21\
\
1. Introduction\
\
   The Internet Protocol version 6 (IPv6) uses the Internet Control\
   Message Protocol (ICMP) as defined for IPv4 [RFC-792], with a number\
   of changes.  The resulting protocol is called ICMPv6 and has an IPv6\
   Next Header value of 58.\
\
   This document describes the format of a set of control messages used\
   in ICMPv6.  It does not describe the procedures for using these\
   messages to achieve functions like Path MTU discovery; these\
   procedures are described in other documents (e.g., [PMTU]).  Other\
   documents may also introduce additional ICMPv6 message types, such as\
   Neighbor Discovery messages [IPv6-DISC], subject to the general rules\
   for ICMPv6 messages given in Section 2 of this document.\
\
   Terminology defined in the IPv6 specification [IPv6] and the IPv6\
   Routing and Addressing specification [IPv6-ADDR] applies to this\
   document as well.\
\
\
\
\
Conta, et al.               Standards Track                     [Page 2]\
\
RFC 4443                 ICMPv6 (ICMP for IPv6)               March 2006\
\
\
   This document obsoletes RFC 2463 [RFC-2463] and updates RFC 2780\
   [RFC-2780].\
\
   The key words "MUST", "MUST NOT", "REQUIRED", "SHALL", "SHALL NOT",\
   "SHOULD", "SHOULD NOT", "RECOMMENDED", "MAY", and "OPTIONAL" in this\
   document are to be interpreted as described in [RFC-2119].\
\
2. ICMPv6 (ICMP for IPv6)\
\
   ICMPv6 is used by IPv6 nodes to report errors encountered in\
   processing packets, and to perform other internet-layer functions,\
   such as diagnostics (ICMPv6 "ping").  ICMPv6 is an integral part of\
   IPv6, and the base protocol (all the messages and behavior required\
   by this specification) MUST be fully implemented by every IPv6 node.\
\
2.1.  Message General Format\
\
   Every ICMPv6 message is preceded by an IPv6 header and zero or more\
   IPv6 extension headers.  The ICMPv6 header is identified by a Next\
   Header value of 58 in the immediately preceding header.  (This is\
   different from the value used to identify ICMP for IPv4.)\
\
   The ICMPv6 messages have the following general format:\
\
       0                   1                   2                   3\
       0 1 2 3 4 5 6 7 8 9 0 1 2 3 4 5 6 7 8 9 0 1 2 3 4 5 6 7 8 9 0 1\
      +-+-+-+-+-+-+-+-+-+-+-+-+-+-+-+-+-+-+-+-+-+-+-+-+-+-+-+-+-+-+-+-+\
      |     Type      |     Code      |          Checksum             |\
      +-+-+-+-+-+-+-+-+-+-+-+-+-+-+-+-+-+-+-+-+-+-+-+-+-+-+-+-+-+-+-+-+\
      |                                                               |\
      +                         Message Body                          +\
      |                                                               |\
\
   The type field indicates the type of the message.  Its value\
   determines the format of the remaining data.\
\
   The code field depends on the message type.  It is used to create an\
   additional level of message granularity.\
\
   The checksum field is used to detect data corruption in the ICMPv6\
   message and parts of the IPv6 header.\
\
   ICMPv6 messages are grouped into two classes: error messages and\
   informational messages.  Error messages are identified as such by a\
   zero in the high-order bit of their message Type field values.  Thus,\
   error messages have message types from 0 to 127; informational\
   messages have message types from 128 to 255.\
\
\
\
\
Conta, et al.               Standards Track                     [Page 3]\
\
RFC 4443                 ICMPv6 (ICMP for IPv6)               March 2006\
\
\
   This document defines the message formats for the following ICMPv6\
   messages:\
\
      ICMPv6 error messages:\
\
          1    Destination Unreachable      (see Section 3.1)\
          2    Packet Too Big               (see Section 3.2)\
          3    Time Exceeded                (see Section 3.3)\
          4    Parameter Problem            (see Section 3.4)\
\
          100  Private experimentation\
          101  Private experimentation\
\
          127  Reserved for expansion of ICMPv6 error messages\
\
      ICMPv6 informational messages:\
\
          128  Echo Request                 (see Section 4.1)\
          129  Echo Reply                   (see Section 4.2)\
\
          200  Private experimentation\
          201  Private experimentation\
\
          255  Reserved for expansion of ICMPv6 informational messages\
\
   Type values 100, 101, 200, and 201 are reserved for private\
   experimentation.  They are not intended for general use.  It is\
   expected that multiple concurrent experiments will be done with the\
   same type values.  Any wide-scale and/or uncontrolled usage should\
   obtain real allocations as defined in Section 6.\
\
   Type values 127 and 255 are reserved for future expansion of the type\
   value range if there is a shortage in the future.  The details of\
   this are left for future work.  One possible way of doing this that\
   would not cause any problems with current implementations is that if\
   the type equals 127 or 255, the code field should be used for the new\
   assignment.  Existing implementations would ignore the new\
   assignments as specified in Section 2.4, (b).  The new messages using\
   these expanded type values could assign fields in the message body\
   for its code values.\
\
   Sections 3 and 4 describe the message formats for the ICMPv6 error\
   message types 1 through 4 and informational message types 128 and\
   129.\
\
\
\
\
\
\
\
Conta, et al.               Standards Track                     [Page 4]\
\
RFC 4443                 ICMPv6 (ICMP for IPv6)               March 2006\
\
\
   Inclusion of, at least, the start of the invoking packet is intended\
   to allow the originator of a packet that has resulted in an ICMPv6\
   error message to identify the upper-layer protocol and process that\
   sent the packet.\
\
2.2.  Message Source Address Determination\
\
   A node that originates an ICMPv6 message has to determine both the\
   Source and Destination IPv6 Addresses in the IPv6 header before\
   calculating the checksum.  If the node has more than one unicast\
   address, it MUST choose the Source Address of the message as follows:\
\
   (a) If the message is a response to a message sent to one of the\
       node's unicast addresses, the Source Address of the reply MUST be\
       that same address.\
\
   (b) If the message is a response to a message sent to any other\
       address, such as\
\
       - a multicast group address,\
       - an anycast address implemented by the node, or\
       - a unicast address that does not belong to the node\
\
      the Source Address of the ICMPv6 packet MUST be a unicast address\
      belonging to the node.  The address SHOULD be chosen according to\
      the rules that would be used to select the source address for any\
      other packet originated by the node, given the destination address\
      of the packet.  However, it MAY be selected in an alternative way\
      if this would lead to a more informative choice of address\
      reachable from the destination of the ICMPv6 packet.\
\
2.3.  Message Checksum Calculation\
\
   The checksum is the 16-bit one's complement of the one's complement\
   sum of the entire ICMPv6 message, starting with the ICMPv6 message\
   type field, and prepended with a "pseudo-header" of IPv6 header\
   fields, as specified in [IPv6, Section 8.1].  The Next Header value\
   used in the pseudo-header is 58.  (The inclusion of a pseudo-header\
   in the ICMPv6 checksum is a change from IPv4; see [IPv6] for the\
   rationale for this change.)\
\
   For computing the checksum, the checksum field is first set to zero.\
\
2.4.  Message Processing Rules\
\
   Implementations MUST observe the following rules when processing\
   ICMPv6 messages (from [RFC-1122]):\
\
\
\
\
Conta, et al.               Standards Track                     [Page 5]\
\
RFC 4443                 ICMPv6 (ICMP for IPv6)               March 2006\
\
\
   (a) If an ICMPv6 error message of unknown type is received at its\
       destination, it MUST be passed to the upper-layer process that\
       originated the packet that caused the error, where this can be\
       identified (see Section 2.4, (d)).\
\
   (b) If an ICMPv6 informational message of unknown type is received,\
       it MUST be silently discarded.\
\
   (c) Every ICMPv6 error message (type < 128) MUST include as much of\
       the IPv6 offending (invoking) packet (the packet that caused the\
       error) as possible without making the error message packet exceed\
       the minimum IPv6 MTU [IPv6].\
\
   (d) In cases where the internet-layer protocol is required to pass an\
       ICMPv6 error message to the upper-layer process, the upper-layer\
       protocol type is extracted from the original packet (contained in\
       the body of the ICMPv6 error message) and used to select the\
       appropriate upper-layer process to handle the error.\
\
       In cases where it is not possible to retrieve the upper-layer\
       protocol type from the ICMPv6 message, the ICMPv6 message is\
       silently dropped after any IPv6-layer processing.  One example of\
       such a case is an ICMPv6 message with an unusually large amount\
       of extension headers that does not have the upper-layer protocol\
       type due to truncation of the original packet to meet the minimum\
       IPv6 MTU [IPv6] limit.  Another example is an ICMPv6 message with\
       an ESP extension header for which it is not possible to decrypt\
       the original packet due to either truncation or the\
       unavailability of the state necessary to decrypt the packet.\
\
   (e) An ICMPv6 error message MUST NOT be originated as a result of\
       receiving the following:\
\
       (e.1) An ICMPv6 error message.\
\
       (e.2) An ICMPv6 redirect message [IPv6-DISC].\
\
       (e.3) A packet destined to an IPv6 multicast address.  (There are\
             two exceptions to this rule: (1) the Packet Too Big Message\
             (Section 3.2) to allow Path MTU discovery to work for IPv6\
             multicast, and (2) the Parameter Problem Message, Code 2\
             (Section 3.4) reporting an unrecognized IPv6 option (see\
             Section 4.2 of [IPv6]) that has the Option Type highest-\
             order two bits set to 10).\
\
       (e.4) A packet sent as a link-layer multicast (the exceptions\
             from e.3 apply to this case, too).\
\
\
\
\
Conta, et al.               Standards Track                     [Page 6]\
\
RFC 4443                 ICMPv6 (ICMP for IPv6)               March 2006\
\
\
       (e.5) A packet sent as a link-layer broadcast (the exceptions\
             from e.3 apply to this case, too).\
\
       (e.6) A packet whose source address does not uniquely identify a\
             single node -- e.g., the IPv6 Unspecified Address, an IPv6\
             multicast address, or an address known by the ICMP message\
             originator to be an IPv6 anycast address.\
\
   (f) Finally, in order to limit the bandwidth and forwarding costs\
       incurred by originating ICMPv6 error messages, an IPv6 node MUST\
       limit the rate of ICMPv6 error messages it originates.  This\
       situation may occur when a source sending a stream of erroneous\
       packets fails to heed the resulting ICMPv6 error messages.\
\
       Rate-limiting of forwarded ICMP messages is out of scope of this\
       specification.\
\
       A recommended method for implementing the rate-limiting function\
       is a token bucket, limiting the average rate of transmission to\
       N, where N can be either packets/second or a fraction of the\
       attached link's bandwidth, but allowing up to B error messages to\
       be transmitted in a burst, as long as the long-term average is\
       not exceeded.\
\
       Rate-limiting mechanisms that cannot cope with bursty traffic\
       (e.g., traceroute) are not recommended; for example, a simple\
       timer-based implementation, allowing an error message every T\
       milliseconds (even with low values for T), is not reasonable.\
\
       The rate-limiting parameters SHOULD be configurable.  In the case\
       of a token-bucket implementation, the best defaults depend on\
       where the implementation is expected to be deployed (e.g., a\
       high-end router vs. an embedded host).  For example, in a\
       small/mid-size device, the possible defaults could be B=10,\
       N=10/s.\
\
   NOTE: THE RESTRICTIONS UNDER (e) AND (f) ABOVE TAKE PRECEDENCE OVER\
   ANY REQUIREMENT ELSEWHERE IN THIS DOCUMENT FOR ORIGINATING ICMP ERROR\
   MESSAGES.\
\
   The following sections describe the message formats for the above\
   ICMPv6 messages.\
\
\
\
\
\
\
\
\
\
Conta, et al.               Standards Track                     [Page 7]\
\
RFC 4443                 ICMPv6 (ICMP for IPv6)               March 2006\
\
\
3. ICMPv6 Error Messages\
\
3.1.  Destination Unreachable Message\
\
       0                   1                   2                   3\
       0 1 2 3 4 5 6 7 8 9 0 1 2 3 4 5 6 7 8 9 0 1 2 3 4 5 6 7 8 9 0 1\
      +-+-+-+-+-+-+-+-+-+-+-+-+-+-+-+-+-+-+-+-+-+-+-+-+-+-+-+-+-+-+-+-+\
      |     Type      |     Code      |          Checksum             |\
      +-+-+-+-+-+-+-+-+-+-+-+-+-+-+-+-+-+-+-+-+-+-+-+-+-+-+-+-+-+-+-+-+\
      |                             Unused                            |\
      +-+-+-+-+-+-+-+-+-+-+-+-+-+-+-+-+-+-+-+-+-+-+-+-+-+-+-+-+-+-+-+-+\
      |                    As much of invoking packet                 |\
      +                as possible without the ICMPv6 packet          +\
      |                exceeding the minimum IPv6 MTU [IPv6]          |\
\
   IPv6 Fields:\
\
   Destination Address\
\
                  Copied from the Source Address field of the invoking\
                  packet.\
\
   ICMPv6 Fields:\
\
   Type           1\
\
   Code           0 - No route to destination\
                  1 - Communication with destination\
                        administratively prohibited\
                  2 - Beyond scope of source address\
                  3 - Address unreachable\
                  4 - Port unreachable\
                  5 - Source address failed ingress/egress policy\
                  6 - Reject route to destination\
\
   Unused         This field is unused for all code values.\
                  It must be initialized to zero by the originator\
                  and ignored by the receiver.\
   Description\
\
   A Destination Unreachable message SHOULD be generated by a router, or\
   by the IPv6 layer in the originating node, in response to a packet\
   that cannot be delivered to its destination address for reasons other\
   than congestion.  (An ICMPv6 message MUST NOT be generated if a\
   packet is dropped due to congestion.)\
\
   If the reason for the failure to deliver is lack of a matching entry\
   in the forwarding node's routing table, the Code field is set to 0.\
\
\
\
Conta, et al.               Standards Track                     [Page 8]\
\
RFC 4443                 ICMPv6 (ICMP for IPv6)               March 2006\
\
\
   (This error can occur only in nodes that do not hold a "default\
   route" in their routing tables.)\
\
   If the reason for the failure to deliver is administrative\
   prohibition (e.g., a "firewall filter"), the Code field is set to 1.\
\
   If the reason for the failure to deliver is that the destination is\
   beyond the scope of the source address, the Code field is set to 2.\
   This condition can occur only when the scope of the source address is\
   smaller than the scope of the destination address (e.g., when a\
   packet has a link-local source address and a global-scope destination\
   address) and the packet cannot be delivered to the destination\
   without leaving the scope of the source address.\
\
   If the reason for the failure to deliver cannot be mapped to any of\
   other codes, the Code field is set to 3.  Example of such cases are\
   an inability to resolve the IPv6 destination address into a\
   corresponding link address, or a link-specific problem of some sort.\
\
   One specific case in which a Destination Unreachable message is sent\
   with a code 3 is in response to a packet received by a router from a\
   point-to-point link, destined to an address within a subnet assigned\
   to that same link (other than one of the receiving router's own\
   addresses).  In such a case, the packet MUST NOT be forwarded back\
   onto the arrival link.\
\
   A destination node SHOULD originate a Destination Unreachable message\
   with Code 4 in response to a packet for which the transport protocol\
   (e.g., UDP) has no listener, if that transport protocol has no\
   alternative means to inform the sender.\
\
   If the reason for the failure to deliver is that the packet with this\
   source address is not allowed due to ingress or egress filtering\
   policies, the Code field is set to 5.\
\
   If the reason for the failure to deliver is that the route to the\
   destination is a reject route, the Code field is set to 6.  This may\
   occur if the router has been configured to reject all the traffic for\
   a specific prefix.\
\
   Codes 5 and 6 are more informative subsets of code 1.\
\
   For security reasons, it is recommended that implementations SHOULD\
   allow sending of ICMP destination unreachable messages to be\
   disabled, preferably on a per-interface basis.\
\
\
\
\
\
\
Conta, et al.               Standards Track                     [Page 9]\
\
RFC 4443                 ICMPv6 (ICMP for IPv6)               March 2006\
\
\
   Upper Layer Notification\
\
   A node receiving the ICMPv6 Destination Unreachable message MUST\
   notify the upper-layer process if the relevant process can be\
   identified (see Section 2.4, (d)).\
\
3.2.  Packet Too Big Message\
\
       0                   1                   2                   3\
       0 1 2 3 4 5 6 7 8 9 0 1 2 3 4 5 6 7 8 9 0 1 2 3 4 5 6 7 8 9 0 1\
      +-+-+-+-+-+-+-+-+-+-+-+-+-+-+-+-+-+-+-+-+-+-+-+-+-+-+-+-+-+-+-+-+\
      |     Type      |     Code      |          Checksum             |\
      +-+-+-+-+-+-+-+-+-+-+-+-+-+-+-+-+-+-+-+-+-+-+-+-+-+-+-+-+-+-+-+-+\
      |                             MTU                               |\
      +-+-+-+-+-+-+-+-+-+-+-+-+-+-+-+-+-+-+-+-+-+-+-+-+-+-+-+-+-+-+-+-+\
      |                    As much of invoking packet                 |\
      +               as possible without the ICMPv6 packet           +\
      |               exceeding the minimum IPv6 MTU [IPv6]           |\
\
   IPv6 Fields:\
\
   Destination Address\
\
                  Copied from the Source Address field of the invoking\
                  packet.\
\
   ICMPv6 Fields:\
\
   Type           2\
\
   Code           Set to 0 (zero) by the originator and ignored by the\
                  receiver.\
\
   MTU            The Maximum Transmission Unit of the next-hop link.\
\
   Description\
\
   A Packet Too Big MUST be sent by a router in response to a packet\
   that it cannot forward because the packet is larger than the MTU of\
   the outgoing link.  The information in this message is used as part\
   of the Path MTU Discovery process [PMTU].\
\
   Originating a Packet Too Big Message makes an exception to one of the\
   rules as to when to originate an ICMPv6 error message.  Unlike other\
   messages, it is sent in response to a packet received with an IPv6\
   multicast destination address, or with a link-layer multicast or\
   link-layer broadcast address.\
\
\
\
\
Conta, et al.               Standards Track                    [Page 10]\
\
RFC 4443                 ICMPv6 (ICMP for IPv6)               March 2006\
\
\
   Upper Layer Notification\
\
   An incoming Packet Too Big message MUST be passed to the upper-layer\
   process if the relevant process can be identified (see Section 2.4,\
   (d)).\
\
3.3.  Time Exceeded Message\
\
       0                   1                   2                   3\
       0 1 2 3 4 5 6 7 8 9 0 1 2 3 4 5 6 7 8 9 0 1 2 3 4 5 6 7 8 9 0 1\
      +-+-+-+-+-+-+-+-+-+-+-+-+-+-+-+-+-+-+-+-+-+-+-+-+-+-+-+-+-+-+-+-+\
      |     Type      |     Code      |          Checksum             |\
      +-+-+-+-+-+-+-+-+-+-+-+-+-+-+-+-+-+-+-+-+-+-+-+-+-+-+-+-+-+-+-+-+\
      |                             Unused                            |\
      +-+-+-+-+-+-+-+-+-+-+-+-+-+-+-+-+-+-+-+-+-+-+-+-+-+-+-+-+-+-+-+-+\
      |                    As much of invoking packet                 |\
      +               as possible without the ICMPv6 packet           +\
      |               exceeding the minimum IPv6 MTU [IPv6]           |\
\
   IPv6 Fields:\
\
   Destination Address\
                  Copied from the Source Address field of the invoking\
                  packet.\
\
   ICMPv6 Fields:\
\
   Type           3\
\
   Code           0 - Hop limit exceeded in transit\
                  1 - Fragment reassembly time exceeded\
\
   Unused         This field is unused for all code values.\
                  It must be initialized to zero by the originator\
                  and ignored by the receiver.\
\
   Description\
\
   If a router receives a packet with a Hop Limit of zero, or if a\
   router decrements a packet's Hop Limit to zero, it MUST discard the\
   packet and originate an ICMPv6 Time Exceeded message with Code 0 to\
   the source of the packet.  This indicates either a routing loop or\
   too small an initial Hop Limit value.\
\
   An ICMPv6 Time Exceeded message with Code 1 is used to report\
   fragment reassembly timeout, as specified in [IPv6, Section 4.5].\
\
\
\
\
\
Conta, et al.               Standards Track                    [Page 11]\
\
RFC 4443                 ICMPv6 (ICMP for IPv6)               March 2006\
\
\
   Upper Layer Notification\
\
   An incoming Time Exceeded message MUST be passed to the upper-layer\
   process if the relevant process can be identified (see Section 2.4,\
   (d)).\
\
3.4.  Parameter Problem Message\
\
       0                   1                   2                   3\
       0 1 2 3 4 5 6 7 8 9 0 1 2 3 4 5 6 7 8 9 0 1 2 3 4 5 6 7 8 9 0 1\
      +-+-+-+-+-+-+-+-+-+-+-+-+-+-+-+-+-+-+-+-+-+-+-+-+-+-+-+-+-+-+-+-+\
      |     Type      |     Code      |          Checksum             |\
      +-+-+-+-+-+-+-+-+-+-+-+-+-+-+-+-+-+-+-+-+-+-+-+-+-+-+-+-+-+-+-+-+\
      |                            Pointer                            |\
      +-+-+-+-+-+-+-+-+-+-+-+-+-+-+-+-+-+-+-+-+-+-+-+-+-+-+-+-+-+-+-+-+\
      |                    As much of invoking packet                 |\
      +               as possible without the ICMPv6 packet           +\
      |               exceeding the minimum IPv6 MTU [IPv6]           |\
\
   IPv6 Fields:\
\
   Destination Address\
\
                  Copied from the Source Address field of the invoking\
                  packet.\
\
   ICMPv6 Fields:\
\
   Type           4\
\
   Code           0 - Erroneous header field encountered\
                  1 - Unrecognized Next Header type encountered\
                  2 - Unrecognized IPv6 option encountered\
\
   Pointer        Identifies the octet offset within the\
                  invoking packet where the error was detected.\
\
                  The pointer will point beyond the end of the ICMPv6\
                  packet if the field in error is beyond what can fit\
                  in the maximum size of an ICMPv6 error message.\
\
   Description\
\
   If an IPv6 node processing a packet finds a problem with a field in\
   the IPv6 header or extension headers such that it cannot complete\
   processing the packet, it MUST discard the packet and SHOULD\
   originate an ICMPv6 Parameter Problem message to the packet's source,\
   indicating the type and location of the problem.\
\
\
\
Conta, et al.               Standards Track                    [Page 12]\
\
RFC 4443                 ICMPv6 (ICMP for IPv6)               March 2006\
\
\
   Codes 1 and 2 are more informative subsets of Code 0.\
\
   The pointer identifies the octet of the original packet's header\
   where the error was detected.  For example, an ICMPv6 message with a\
   Type field of 4, Code field of 1, and Pointer field of 40 would\
   indicate that the IPv6 extension header following the IPv6 header of\
   the original packet holds an unrecognized Next Header field value.\
\
   Upper Layer Notification\
\
   A node receiving this ICMPv6 message MUST notify the upper-layer\
   process if the relevant process can be identified (see Section 2.4,\
   (d)).\
\
4. ICMPv6 Informational Messages\
\
4.1.  Echo Request Message\
\
       0                   1                   2                   3\
       0 1 2 3 4 5 6 7 8 9 0 1 2 3 4 5 6 7 8 9 0 1 2 3 4 5 6 7 8 9 0 1\
      +-+-+-+-+-+-+-+-+-+-+-+-+-+-+-+-+-+-+-+-+-+-+-+-+-+-+-+-+-+-+-+-+\
      |     Type      |     Code      |          Checksum             |\
      +-+-+-+-+-+-+-+-+-+-+-+-+-+-+-+-+-+-+-+-+-+-+-+-+-+-+-+-+-+-+-+-+\
      |           Identifier          |        Sequence Number        |\
      +-+-+-+-+-+-+-+-+-+-+-+-+-+-+-+-+-+-+-+-+-+-+-+-+-+-+-+-+-+-+-+-+\
      |     Data ...\
      +-+-+-+-+-\
\
   IPv6 Fields:\
\
   Destination Address\
\
                  Any legal IPv6 address.\
\
   ICMPv6 Fields:\
\
   Type           128\
\
   Code           0\
\
   Identifier     An identifier to aid in matching Echo Replies\
                  to this Echo Request.  May be zero.\
\
\
\
\
\
\
\
\
\
Conta, et al.               Standards Track                    [Page 13]\
\
RFC 4443                 ICMPv6 (ICMP for IPv6)               March 2006\
\
\
   Sequence Number\
\
                  A sequence number to aid in matching Echo Replies\
                  to this Echo Request.  May be zero.\
\
   Data           Zero or more octets of arbitrary data.\
\
   Description\
\
   Every node MUST implement an ICMPv6 Echo responder function that\
   receives Echo Requests and originates corresponding Echo Replies.  A\
   node SHOULD also implement an application-layer interface for\
   originating Echo Requests and receiving Echo Replies, for diagnostic\
   purposes.\
\
   Upper Layer Notification\
\
   Echo Request messages MAY be passed to processes receiving ICMP\
   messages.\
\
4.2.  Echo Reply Message\
\
       0                   1                   2                   3\
       0 1 2 3 4 5 6 7 8 9 0 1 2 3 4 5 6 7 8 9 0 1 2 3 4 5 6 7 8 9 0 1\
      +-+-+-+-+-+-+-+-+-+-+-+-+-+-+-+-+-+-+-+-+-+-+-+-+-+-+-+-+-+-+-+-+\
      |     Type      |     Code      |          Checksum             |\
      +-+-+-+-+-+-+-+-+-+-+-+-+-+-+-+-+-+-+-+-+-+-+-+-+-+-+-+-+-+-+-+-+\
      |           Identifier          |        Sequence Number        |\
      +-+-+-+-+-+-+-+-+-+-+-+-+-+-+-+-+-+-+-+-+-+-+-+-+-+-+-+-+-+-+-+-+\
      |     Data ...\
      +-+-+-+-+-\
\
   IPv6 Fields:\
\
   Destination Address\
\
                  Copied from the Source Address field of the invoking\
                  Echo Request packet.\
\
   ICMPv6 Fields:\
\
   Type           129\
\
   Code           0\
\
   Identifier     The identifier from the invoking Echo Request message.\
\
\
\
\
\
Conta, et al.               Standards Track                    [Page 14]\
\
RFC 4443                 ICMPv6 (ICMP for IPv6)               March 2006\
\
\
   Sequence Number\
\
                  The sequence number from the invoking Echo Request\
                  message.\
\
   Data           The data from the invoking Echo Request message.\
\
   Description\
\
   Every node MUST implement an ICMPv6 Echo responder function that\
   receives Echo Requests and originates corresponding Echo Replies.  A\
   node SHOULD also implement an application-layer interface for\
   originating Echo Requests and receiving Echo Replies, for diagnostic\
   purposes.\
\
   The source address of an Echo Reply sent in response to a unicast\
   Echo Request message MUST be the same as the destination address of\
   that Echo Request message.\
\
   An Echo Reply SHOULD be sent in response to an Echo Request message\
   sent to an IPv6 multicast or anycast address.  In this case, the\
   source address of the reply MUST be a unicast address belonging to\
   the interface on which the Echo Request message was received.\
\
   The data received in the ICMPv6 Echo Request message MUST be returned\
   entirely and unmodified in the ICMPv6 Echo Reply message.\
\
   Upper Layer Notification\
\
   Echo Reply messages MUST be passed to the process that originated an\
   Echo Request message.  An Echo Reply message MAY be passed to\
   processes that did not originate the Echo Request message.\
\
   Note that there is no limitation on the amount of data that can be\
   put in Echo Request and Echo Reply Messages.\
\
5. Security Considerations\
\
5.1.  Authentication and Confidentiality of ICMP Messages\
\
   ICMP protocol packet exchanges can be authenticated using the IP\
   Authentication Header [IPv6-AUTH] or IP Encapsulating Security\
   Payload Header [IPv6-ESP].  Confidentiality for the ICMP protocol\
   packet exchanges can be achieved using the IP Encapsulating Security\
   Payload Header [IPv6-ESP].\
\
   [SEC-ARCH] describes the IPsec handling of ICMP traffic in detail.\
\
\
\
\
Conta, et al.               Standards Track                    [Page 15]\
\
RFC 4443                 ICMPv6 (ICMP for IPv6)               March 2006\
\
\
5.2.  ICMP Attacks\
\
   ICMP messages may be subject to various attacks.  A complete\
   discussion can be found in the IP Security Architecture [IPv6-SA].  A\
   brief discussion of these attacks and their prevention follows:\
\
   1. ICMP messages may be subject to actions intended to cause the\
      receiver to believe the message came from a different source from\
      that of the message originator.  The protection against this\
      attack can be achieved by applying the IPv6 Authentication\
      mechanism [IPv6-AUTH] to the ICMP message.\
\
   2. ICMP messages may be subject to actions intended to cause the\
      message or the reply to it to go to a destination different from\
      that of the message originator's intention.  The protection\
      against this attack can be achieved by using the Authentication\
      Header [IPv6-AUTH] or the Encapsulating Security Payload Header\
      [IPv6-ESP].  The Authentication Header provides the protection\
      against change for the source and the destination address of the\
      IP packet.  The Encapsulating Security Payload Header does not\
      provide this protection, but the ICMP checksum calculation\
      includes the source and the destination addresses, and the\
      Encapsulating Security Payload Header protects the checksum.\
      Therefore, the combination of ICMP checksum and the Encapsulating\
      Security Payload Header provides protection against this attack.\
      The protection provided by the Encapsulating Security Payload\
      Header will not be as strong as the protection provided by the\
      Authentication Header.\
\
   3. ICMP messages may be subject to changes in the message fields, or\
      payload.  The authentication [IPv6-AUTH] or encryption [IPv6-ESP]\
      of the ICMP message protects against such actions.\
\
   4. ICMP messages may be used to attempt denial-of-service attacks by\
      sending back to back erroneous IP packets.  An implementation that\
      correctly followed Section 2.4, paragraph (f), of this\
      specification, would be protected by the ICMP error rate limiting\
      mechanism.\
\
   5. The exception number 2 of rule e.3 in Section 2.4 gives a\
      malicious node the opportunity to cause a denial-of-service attack\
      to a multicast source.  A malicious node can send a multicast\
      packet with an unknown destination option marked as mandatory,\
      with the IPv6 source address of a valid multicast source.  A large\
      number of destination nodes will send an ICMP Parameter Problem\
      Message to the multicast source, causing a denial-of-service\
      attack.  The way multicast traffic is forwarded by the multicast\
      routers requires that the malicious node be part of the correct\
\
\
\
Conta, et al.               Standards Track                    [Page 16]\
\
RFC 4443                 ICMPv6 (ICMP for IPv6)               March 2006\
\
\
      multicast path, i.e., near to the multicast source.  This attack\
      can only be avoided by securing the multicast traffic.  The\
      multicast source should be careful while sending multicast traffic\
      with the destination options marked as mandatory, because they can\
      cause a denial-of-service attack to themselves if the destination\
      option is unknown to a large number of destinations.\
\
   6. As the ICMP messages are passed to the upper-layer processes, it\
      is possible to perform attacks on the upper layer protocols (e.g.,\
      TCP) with ICMP [TCP-attack].  It is recommended that the upper\
      layers perform some form of validation of ICMP messages (using the\
      information contained in the payload of the ICMP message) before\
      acting upon them.  The actual validation checks are specific to\
      the upper layers and are out of the scope of this specification.\
      Protecting the upper layer with IPsec mitigates these attacks.\
\
      ICMP error messages signal network error conditions that were\
      encountered while processing an internet datagram.  Depending on\
      the particular scenario, the error conditions being reported might\
      or might not get solved in the near term.  Therefore, reaction to\
      ICMP error messages may depend not only on the error type and code\
      but also on other factors, such as the time at which the error\
      messages are received, previous knowledge of the network error\
      conditions being reported, and knowledge of the network scenario\
      in which the receiving host is operating.\
\
6. IANA Considerations\
\
6.1.  Procedure for New ICMPV6 Type and Code Value Assignments\
\
   The IPv6 ICMP header defined in this document contains the following\
   fields that carry values assigned from IANA-managed name spaces: Type\
   and Code.  Code field values are defined relative to a specific Type\
   value.\
\
   Values for the IPv6 ICMP Type fields are allocated using the\
   following procedure:\
\
   1. The IANA should allocate and permanently register new ICMPv6 type\
      codes from IETF RFC publication.  This is for all RFC types,\
      including standards track, informational, and experimental status,\
      that originate from the IETF and have been approved by the IESG\
      for publication.\
\
   2. IETF working groups with working group consensus and area director\
      approval can request reclaimable ICMPV6 type code assignments from\
      the IANA.  The IANA will tag the values as "reclaimable in\
      future".\
\
\
\
Conta, et al.               Standards Track                    [Page 17]\
\
RFC 4443                 ICMPv6 (ICMP for IPv6)               March 2006\
\
\
      The "reclaimable in the future" tag will be removed when an RFC is\
      published that documents the protocol as defined in 1.  This will\
      make the assignment permanent and update the reference on the IANA\
      web pages.\
\
      At the point where the ICMPv6 type values are 85% assigned, the\
      IETF will review the assignments tagged "reclaimable in the\
      future" and inform the IANA which ones should be reclaimed and\
      reassigned.\
\
   3. Requests for new ICMPv6 type value assignments from outside the\
      IETF are only made through the publication of an IETF document,\
      per 1 above.  Note also that documents published as "RFC Editor\
      contributions" [RFC-3978] are not considered IETF documents.\
\
   The assignment of new Code values for the Type values defined in this\
   document require standards action or IESG approval.  The policy for\
   assigning Code values for new IPv6 ICMP Types not defined in this\
   document should be defined in the document defining the new Type\
   values.\
\
6.2.  Assignments for This Document\
\
   The following has updated assignments located at:\
\
      http://www.iana.org/assignments/icmpv6-parameters\
\
   The IANA has reassigned ICMPv6 type 1 "Destination Unreachable" code\
   2, which was unassigned in [RFC-2463], to:\
\
         2 - Beyond scope of source address\
\
   The IANA has assigned the following two new codes values for ICMPv6\
   type 1 "Destination Unreachable":\
\
         5 - Source address failed ingress/egress policy\
         6 - Reject route to destination\
\
   The IANA has assigned the following new type values:\
\
         100  Private experimentation\
         101  Private experimentation\
\
         127  Reserved for expansion of ICMPv6 error messages\
\
         200  Private experimentation\
         201  Private experimentation\
\
\
\
\
Conta, et al.               Standards Track                    [Page 18]\
\
RFC 4443                 ICMPv6 (ICMP for IPv6)               March 2006\
\
\
         255  Reserved for expansion of ICMPv6 informational messages\
\
7. References\
\
7.1.  Normative References\
\
   [IPv6]       Deering, S. and R. Hinden, "Internet Protocol, Version 6\
                (IPv6) Specification", RFC 2460, December 1998.\
\
   [IPv6-DISC]  Narten, T., Nordmark, E., and W. Simpson, "Neighbor\
                Discovery for IP Version 6 (IPv6)", RFC 2461, December\
                1998.\
\
   [RFC-792]    Postel, J., "Internet Control Message Protocol", STD 5,\
                RFC 792, September 1981.\
\
   [RFC-2463]   Conta, A. and S. Deering, "Internet Control Message\
                Protocol (ICMPv6) for the Internet Protocol Version 6\
                (IPv6) Specification", RFC 2463, December 1998.\
\
   [RFC-1122]   Braden, R., "Requirements for Internet Hosts -\
                Communication Layers", STD 3, RFC 1122, October 1989.\
\
   [RFC-2119]   Bradner, S., "Key words for use in RFCs to Indicate\
                Requirement Levels", BCP 14, RFC 2119, March 1997.\
\
   [RFC-3978]   Bradner, S., "IETF Rights in Contributions", BCP 78, RFC\
                3978, March 2005.\
\
7.2.  Informative References\
\
   [RFC-2780]   Bradner, S. and V. Paxson, "IANA Allocation Guidelines\
                For Values In the Internet Protocol and Related\
                Headers", BCP 37, RFC 2780, March 2000.\
\
   [IPv6-ADDR]  Hinden, R. and S. Deering, "Intpernet Protocol Version 6\
                (IPv6) Addressing Architecture", RFC 3513, April 2003.\
\
   [PMTU]       McCann, J., Deering, S., and J. Mogul, "Path MTU\
                Discovery for IP version 6", RFC 1981, August 1996.\
\
   [IPv6-SA]    Kent, S. and R. Atkinson, "Security Architecture for the\
                Internet Protocol", RFC 2401, November 1998.\
\
   [IPv6-AUTH]  Kent, S., "IP Authentication Header", RFC 4302, December\
                2005.\
\
\
\
\
\
Conta, et al.               Standards Track                    [Page 19]\
\
RFC 4443                 ICMPv6 (ICMP for IPv6)               March 2006\
\
\
   [IPv6-ESP]   Kent, S., "IP Encapsulating Security Payload (ESP)", RFC\
                4203, December 2005.\
\
   [SEC-ARCH]   Kent, S. and K. Seo, "Security Architecture for the\
                Internet Protocol", RFC 4301, December 2005.\
\
   [TCP-attack] Gont, F., "ICMP attacks against TCP", Work in Progress.\
\
8.  Acknowledgements\
\
   The document is derived from previous ICMP documents of the SIPP and\
   IPng working group.\
\
   The IPng working group, and particularly Robert Elz, Jim Bound, Bill\
   Simpson, Thomas Narten, Charlie Lynn, Bill Fink, Scott Bradner,\
   Dimitri Haskin, Bob Hinden, Jun-ichiro Itojun Hagino, Tatuya Jinmei,\
   Brian Zill, Pekka Savola, Fred Templin, and Elwyn Davies (in\
   chronological order) provided extensive review information and\
   feedback.\
\
   Bob Hinden was the document editor for this document.\
\
\
\
\
\
\
\
\
\
\
\
\
\
\
\
\
\
\
\
\
\
\
\
\
\
\
\
\
\
\
Conta, et al.               Standards Track                    [Page 20]\
\
RFC 4443                 ICMPv6 (ICMP for IPv6)               March 2006\
\
\
Appendix A - Changes since RFC 2463\
\
   The following changes were made from RFC 2463:\
\
   - Edited the Abstract to make it a little more elaborate.\
\
   - Corrected typos in Section 2.4, where references to sub-bullet e.2\
     were supposed to be references to e.3.\
\
   - Removed the Timer-based and the Bandwidth-based methods from the\
     example rate-limiting mechanism for ICMP error messages.  Added\
     Token-bucket based method.\
\
   - Added specification that all ICMP error messages shall have exactly\
     32 bits of type-specific data, so that receivers can reliably find\
     the embedded invoking packet even when they don't recognize the\
     ICMP message Type.\
\
   - In the description of Destination Unreachable messages, Code 3,\
     added rule prohibiting forwarding of packets back onto point-to-\
     point links from which they were received, if their destination\
     addresses belong to the link itself ("anti-ping-ponging" rule).\
\
   - Added description of Time Exceeded Code 1 (fragment reassembly\
     timeout).\
\
   - Added "beyond scope of source address", "source address failed\
     ingress/egress policy", and "reject route to destination" messages\
     to the family of "unreachable destination" type ICMP error messages\
     (Section 3.1).\
\
   - Reserved some ICMP type values for experimentation.\
\
   - Added a NOTE in Section 2.4 that specifies ICMP message processing\
     rules precedence.\
\
   - Added ICMP REDIRECT to the list in Section 2.4, (e) of cases in\
     which ICMP error messages are not to be generated.\
\
   - Made minor editorial changes in Section 2.3 on checksum\
     calculation, and in Section 5.2.\
\
   - Clarified in Section 4.2, regarding the Echo Reply Message; the\
     source address of an Echo Reply to an anycast Echo Request should\
     be a unicast address, as in the case of multicast.\
\
\
\
\
\
\
Conta, et al.               Standards Track                    [Page 21]\
\
RFC 4443                 ICMPv6 (ICMP for IPv6)               March 2006\
\
\
   - Revised the Security Considerations section.  Added the use of the\
     Encapsulating Security Payload Header for authentication.  Changed\
     the requirement of an option of "not allowing unauthenticated ICMP\
     messages" to MAY from SHOULD.\
\
   - Added a new attack in the list of possible ICMP attacks in Section\
     5.2.\
\
   - Separated References into Normative and Informative.\
\
   - Added reference to RFC 2780 "IANA Allocation Guidelines For Values\
     In the Internet Protocol and Related Headers".  Also added a note\
     that this document updates RFC 2780.\
\
   - Added a procedure for new ICMPv6 Type and Code value assignments in\
     the IANA Considerations section.\
\
   - Replaced word "send" with "originate" to make it clear that ICMP\
     packets being forwarded are out of scope of this specification.\
\
   - Changed the ESP and AH references to the updated ESP and AH\
     documents.\
\
   - Added reference to the updated IPsec Security Architecture\
     document.\
\
   - Added a SHOULD requirement for allowing the sending of ICMP\
     destination unreachable messages to be disabled.\
\
   - Simplified the source address selection of the ICMPv6 packet.\
\
   - Reorganized the General Message Format (Section 2.1).\
\
   - Removed the general packet format from Section 2.1.  It refers to\
     Sections 3 and 4 for packet formats now.\
\
   - Added text about attacks to the transport protocols that could\
     potentially be caused by ICMP.\
\
\
\
\
\
\
\
\
\
\
\
\
\
Conta, et al.               Standards Track                    [Page 22]\
\
RFC 4443                 ICMPv6 (ICMP for IPv6)               March 2006\
\
\
Authors' Addresses\
\
   Alex Conta\
   Transwitch Corporation\
   3 Enterprise Drive\
   Shelton, CT 06484\
   USA\
\
   EMail: aconta@txc.com\
\
\
   Stephen Deering\
   Cisco Systems, Inc.\
   170 West Tasman Drive\
   San Jose, CA 95134-1706\
   USA\
\
\
   Mukesh Gupta, Ed.\
   Tropos Networks\
   555 Del Rey Avenue\
   Sunnyvale, CA 94085\
\
   Phone: +1 408-331-6889\
   EMail: mukesh.gupta@tropos.com\
\
\
\
\
\
\
\
\
\
\
\
\
\
\
\
\
\
\
\
\
\
\
\
\
\
\
Conta, et al.               Standards Track                    [Page 23]\
\
RFC 4443                 ICMPv6 (ICMP for IPv6)               March 2006\
\
\
Full Copyright Statement\
\
   Copyright (C) The Internet Society (2006).\
\
   This document is subject to the rights, licenses and restrictions\
   contained in BCP 78, and except as set forth therein, the authors\
   retain all their rights.\
\
   This document and the information contained herein are provided on an\
   "AS IS" basis and THE CONTRIBUTOR, THE ORGANIZATION HE/SHE REPRESENTS\
   OR IS SPONSORED BY (IF ANY), THE INTERNET SOCIETY AND THE INTERNET\
   ENGINEERING TASK FORCE DISCLAIM ALL WARRANTIES, EXPRESS OR IMPLIED,\
   INCLUDING BUT NOT LIMITED TO ANY WARRANTY THAT THE USE OF THE\
   INFORMATION HEREIN WILL NOT INFRINGE ANY RIGHTS OR ANY IMPLIED\
   WARRANTIES OF MERCHANTABILITY OR FITNESS FOR A PARTICULAR PURPOSE.\
\
Intellectual Property\
\
   The IETF takes no position regarding the validity or scope of any\
   Intellectual Property Rights or other rights that might be claimed to\
   pertain to the implementation or use of the technology described in\
   this document or the extent to which any license under such rights\
   might or might not be available; nor does it represent that it has\
   made any independent effort to identify any such rights.  Information\
   on the procedures with respect to rights in RFC documents can be\
   found in BCP 78 and BCP 79.\
\
   Copies of IPR disclosures made to the IETF Secretariat and any\
   assurances of licenses to be made available, or the result of an\
   attempt made to obtain a general license or permission for the use of\
   such proprietary rights by implementers or users of this\
   specification can be obtained from the IETF on-line IPR repository at\
   http://www.ietf.org/ipr.\
\
   The IETF invites any interested party to bring to its attention any\
   copyrights, patents or patent applications, or other proprietary\
   rights that may cover technology that may be required to implement\
   this standard.  Please address the information to the IETF at\
   ietf-ipr@ietf.org.\
\
Acknowledgement\
\
   Funding for the RFC Editor function is provided by the IETF\
   Administrative Support Activity (IASA).\
\
\
\
\
\
\
\
Conta, et al.               Standards Track                    [Page 24]\
\

doc 5
  field 0
    name titolo
    type string
    value rfc4442.txt
  field 1
    name contenuto
    type string
    value \
\
\
\
\
\
Network Working Group                                           S. Fries\
Request for Comments: 4442                                 H. Tschofenig\
Category: Standards Track                                        Siemens\
                                                              March 2006\
\
\
                             Bootstrapping\
      Timed Efficient Stream Loss-Tolerant Authentication (TESLA)\
\
Status of This Memo\
\
   This document specifies an Internet standards track protocol for the\
   Internet community, and requests discussion and suggestions for\
   improvements.  Please refer to the current edition of the "Internet\
   Official Protocol Standards" (STD 1) for the standardization state\
   and status of this protocol.  Distribution of this memo is unlimited.\
\
Copyright Notice\
\
   Copyright (C) The Internet Society (2006).\
\
Abstract\
\
   TESLA, the Timed Efficient Stream Loss-tolerant Authentication\
   protocol, provides source authentication in multicast scenarios.\
   TESLA is an efficient protocol with low communication and computation\
   overhead that scales to large numbers of receivers and also tolerates\
   packet loss.  TESLA is based on loose time synchronization between\
   the sender and the receivers.  Source authentication is realized in\
   TESLA by using Message Authentication Code (MAC) chaining.  The use\
   of TESLA within the Secure Real-time Transport Protocol (SRTP) has\
   been published, targeting multicast authentication in scenarios where\
   SRTP is applied to protect the multimedia data.  This solution\
   assumes that TESLA parameters are made available by out-of-band\
   mechanisms.\
\
   This document specifies payloads for the Multimedia Internet Keying\
   (MIKEY) protocol for bootstrapping TESLA for source authentication of\
   secure group communications using SRTP.  TESLA may be bootstrapped\
   using one of the MIKEY key management approaches, e.g., by using a\
   digitally signed MIKEY message sent via unicast, multicast, or\
   broadcast.\
\
\
\
\
\
\
\
\
\
Fries & Tschofenig          Standards Track                     [Page 1]\
\
RFC 4442                  Bootstrapping TESLA                 March 2006\
\
\
Table of Contents\
\
   1. Introduction ....................................................3\
   2. Terminology .....................................................4\
   3. TESLA Parameter Overview ........................................4\
   4. Parameter Encoding within MIKEY .................................6\
      4.1. Security Policy (SP) Payload ...............................6\
      4.2. TESLA Policy ...............................................7\
      4.3. Time Synchronization .......................................8\
      4.4. Key Data Transport within MIKEY's General\
           Extension Payload .........................................10\
   5. Security Considerations ........................................11\
      5.1. Man-in-the-Middle Attack ..................................11\
      5.2. Downgrading Attack ........................................12\
      5.3. Denial of Service Attack ..................................12\
      5.4. Replay Attack .............................................13\
      5.5. Traffic Analysis ..........................................13\
   6. IANA Considerations ............................................14\
   7. Acknowledgements ...............................................15\
   8. References .....................................................16\
      8.1. Normative References ......................................16\
      8.2. Informative References ....................................16\
\
\
\
\
\
\
\
\
\
\
\
\
\
\
\
\
\
\
\
\
\
\
\
\
\
\
\
\
\
Fries & Tschofenig          Standards Track                     [Page 2]\
\
RFC 4442                  Bootstrapping TESLA                 March 2006\
\
\
1.  Introduction\
\
   In many multicast, broadcast, and unicast communication scenarios, it\
   is necessary to guarantee that a received message has been sent from\
   a dedicated source and has not been altered in transit.  In unicast\
   communication, commonly a pairwise security association exists that\
   enables the validation of message integrity and data origin.  The\
   approach in group-based communication is different, as here a key is\
   normally shared between the members of a group and thus may not be\
   used for data origin authentication.  As in some applications a\
   dedicated identification of a sender is required, there exists the\
   requirement to support data origin authentication also in multicast\
   scenarios.  One of the methods supporting this is TESLA [RFC4082].\
   TESLA provides source authentication in multicast scenarios by using\
   MAC chaining.  It is based on loose time synchronization between the\
   sender and the receivers.\
\
   [RFC4383] describes extensions for SRTP [RFC3711] in order to support\
   TESLA [RFC4082] for source authentication in multicast scenarios.\
   SRTP needs dedicated cryptographic context describing the security\
   parameter and security policy per multimedia session to be protected.\
   This cryptographic context needs to be enhanced with a set of TESLA\
   parameters.  It is necessary to provide these parameters before the\
   actual multicast session starts.  [RFC4383] does not address the\
   bootstrapping for these parameters.\
\
   This document details bootstrapping of TESLA parameters in terms of\
   parameter distribution for TESLA policy as well as the initial key,\
   using the Multimedia Internet Keying (MIKEY) [RFC3830] protocol.\
   MIKEY defines an authentication and key management framework that can\
   be used for real-time applications (both for peer-to-peer\
   communication and group communication).  In particular, [RFC3830] is\
   defined in a way that is intended to support SRTP in the first place\
   but is open to enhancements to be used for other purposes too.\
   Following the description in [RFC3830], MIKEY is targeted for point-\
   to-point as well as group communication.  In the context of group\
   communication, an administrator entity can distribute session keys to\
   the associated entities participating in the communication session.\
   This scenario is also applicable for TESLA where one entity may\
   provide information to many others in a way that the integrity of the\
   communicated information can be assured.  The combination of MIKEY\
   and TESLA supports this group-based approach by utilizing the MIKEY\
   framework to distribute TESLA parameter information to all involved\
   entities.  Note that this document focuses only on the distribution\
   of the parameters, not on the generation of those parameters.\
\
   MIKEY [RFC3830] itself describes three authentication and key\
   exchange protocols (symmetric key encryption, public key encryption,\
\
\
\
Fries & Tschofenig          Standards Track                     [Page 3]\
\
RFC 4442                  Bootstrapping TESLA                 March 2006\
\
\
   and signed Diffie-Hellman).  Extensions to the MIKEY key exchange\
   methods have been defined.  A fourth key distribution method is\
   provided by [DHHMAC] and describes a symmetrically protected Diffie-\
   Hellman key agreement.  A further option has been proposed in [RSA-R]\
   that describes an enhanced asymmetric exchange variant, also\
   supporting inband certificate exchange.  All the different key\
   management schemes mentioned above may be used to provide the TESLA\
   parameters.  The required TESLA parameters to be exchanged are\
   already described in [RFC4383], while this document describes their\
   transport within MIKEY.\
\
   The following security requirements have to be placed on the exchange\
   of TESLA parameters:\
\
   o  Authentication and Integrity MUST be provided when sending the\
      TESLA parameters, especially for the initial key.\
   o  Confidentiality MAY be provided for the TESLA parameters.\
\
   These security requirements apply to the TESLA bootstrapping\
   procedure only.  Security requirements for applications using TESLA\
   are beyond the scope of this document.  Security aspects that relate\
   to TESLA itself are described in [RFC4082], and security issues for\
   TESLA usage for SRTP are covered in [RFC4383].\
\
   It is important to note that this document is one piece of a complete\
   solution.  Assuming that media traffic is to be secured using TESLA\
   as described in [RFC4383], then (a) keying material and (b)\
   parameters for TESLA are required.  This document contributes the\
   parameters and the authentication methods used in MIKEY to provide\
   the keying material.  The parameter exchange for TESLA also needs to\
   be secured against tampering.  This protection is also provided by\
   MIKEY.\
\
2.  Terminology\
\
   The key words "MUST", "MUST NOT", "REQUIRED", "SHALL", "SHALL NOT",\
   "SHOULD", "SHOULD NOT", "RECOMMENDED", "MAY", and "OPTIONAL" in this\
   document are to be interpreted as described in RFC 2119 [RFC2119].\
\
3.  TESLA Parameter Overview\
\
   According to [RFC4383], a number of transform-dependent parameters\
   need to be provided for proper TESLA operation.  The complete list of\
   parameters can be found in Section 4.3 of [RFC4383].  Note that\
   parameter 10 of [RFC4383], describing the lag of the receiver clock\
   relative to the sender clock, is omitted in this document since it\
   can be computed.\
\
\
\
\
Fries & Tschofenig          Standards Track                     [Page 4]\
\
RFC 4442                  Bootstrapping TESLA                 March 2006\
\
\
   MIKEY already requires synchronized clocks, which also provides for\
   synchronization for TESLA.  Moreover, Section 4.3 states an option to\
   use MIKEY for clock drift determination between the sender and\
   receiver.  Thus, this parameter does not need to be transmitted in\
   MIKEY directly.\
\
   The information in brackets provides the default values as specified\
   in Section 6.2 of [RFC4383].\
\
   1.   An identifier for the PRF (TESLA PRF), implementing the one-way\
        function F(x) in TESLA (to derive the keys in the chain), and\
        the one-way function F'(x) in TESLA (to derive the keys for the\
        TESLA MAC, from the keys in the chain), e.g., to indicate the\
        keyed hash function (default HMAC-SHA1).\
\
   2.   A non-negative integer, determining the length of the F output,\
        i.e., the length of the keys in the chain, which is also the key\
        disclosed in an SRTP packet if TESLA is used in the SRTP context\
        (default 160 bit).\
\
   3.   A non-negative integer, determining the length of the output of\
        F', i.e., the length of the key for the TESLA MAC (default 160\
        bit).\
\
   4.   An identifier for the TESLA MAC that accepts the output of F'(x)\
        as its key, e.g., to indicate a keyed hashing function (default\
        HMAC-SHA1).\
\
   5.   A non-negative integer, determining the length of the output of\
        the TESLA MAC (default 80 bit).\
\
   6.   The beginning of the session for which a key will be applied.\
\
   7.   The interval duration (in milliseconds) for which a dedicated\
        key will be used.\
\
   8.   The key disclosure delay (in number of intervals) characterizes\
        the period after which the key will be sent to the involved\
        entities (e.g., as part of SRTP packets).\
\
   9.   Non-negative integer, determining the length of the key chain,\
        which is determined based on the expected duration of the\
        stream.\
\
   10.  The initial key of the chain to which the sender has committed\
        himself.\
\
\
\
\
\
Fries & Tschofenig          Standards Track                     [Page 5]\
\
RFC 4442                  Bootstrapping TESLA                 March 2006\
\
\
4.  Parameter Encoding within MIKEY\
\
   As mentioned in Section 3, TESLA parameters need to be transported\
   before actually starting a session.  MIKEY currently only defines a\
   payload for transporting the SRTP policy (see Section 6.10 of\
   [RFC3830]).  This section describes the enhancement of MIKEY to allow\
   the transport of a TESLA policy and additionally the initial TESLA\
   key.\
\
4.1.  Security Policy (SP) Payload\
\
   The Security Policy payload defines a set of policies that apply to a\
   specific security protocol.  The definition here relies on the\
   security policy payload definition in [RFC3830].\
\
    0                   1                   2                   3\
    0 1 2 3 4 5 6 7 8 9 0 1 2 3 4 5 6 7 8 9 0 1 2 3 4 5 6 7 8 9 0 1\
   +-+-+-+-+-+-+-+-+-+-+-+-+-+-+-+-+-+-+-+-+-+-+-+-+-+-+-+-+-+-+-+-+\
   ! Next payload  ! Policy no     ! Prot type     ! Policy param  ~\
   +-+-+-+-+-+-+-+-+-+-+-+-+-+-+-+-+-+-+-+-+-+-+-+-+-+-+-+-+-+-+-+-+\
   ~ length (cont) ! Policy param                                  ~\
   +-+-+-+-+-+-+-+-+-+-+-+-+-+-+-+-+-+-+-+-+-+-+-+-+-+-+-+-+-+-+-+-+\
\
      *  Next payload (8 bits):\
         Identifies the payload that is added after\
         this payload.  See Section 6.1 of [RFC3830] for\
         more details.\
\
      *  Policy no (8 bits):\
         Each security policy payload must be given a\
         distinct number for the current MIKEY session by the\
         local peer.  This number is used to map a cryptographic session\
         to a specific policy (see also Section 6.1.1 of [RFC3830]).\
\
      *  Prot type (8 bits):\
         This value defines the security protocol.\
         A second value needs to be defined as shown below:\
         (MIKEY already defines the value 0.)\
\
         Prot type     | Value |\
         ---------------------------\
         SRTP          |     0 |\
         TESLA         |     1 |\
\
      *  Policy param length (16 bits):\
         This field defines the total length of the\
         policy parameters for the selected security protocol.\
\
\
\
\
Fries & Tschofenig          Standards Track                     [Page 6]\
\
RFC 4442                  Bootstrapping TESLA                 March 2006\
\
\
      *  Policy param (variable length):\
         This field defines the policy for the specific\
         security protocol.\
\
   The Policy param part is built up by a set of Type/Length/Value (TLV)\
   payloads.  For each security protocol, a set of possible type/value\
   pairs can be negotiated as defined.\
\
    0                   1                   2                   3\
    0 1 2 3 4 5 6 7 8 9 0 1 2 3 4 5 6 7 8 9 0 1 2 3 4 5 6 7 8 9 0 1\
   +-+-+-+-+-+-+-+-+-+-+-+-+-+-+-+-+-+-+-+-+-+-+-+-+-+-+-+-+-+-+-+-+\
   ! Type          ! Length        ! Value                         ~\
   +-+-+-+-+-+-+-+-+-+-+-+-+-+-+-+-+-+-+-+-+-+-+-+-+-+-+-+-+-+-+-+-+\
\
      *  Type (8 bits):\
         Specifies the type of the parameter.\
\
      *  Length (8 bits):\
         Specifies the length of the Value field (in bytes).\
\
      *  Value (variable length):\
         Specifies the value of the parameter.\
\
4.2.  TESLA Policy\
\
   This policy specifies the parameters for TESLA.  The types/values\
   that can be negotiated are defined by the following table.  The\
   concrete default values are taken from [RFC4383], but other values\
   may also be used:\
\
      Type | Meaning                                | Possible values\
      ---------------------------------------------------------------\
         1 | PRF identifier for f and f', realising | see below\
             F(x) and F'(x)\
         2 | Length of PRF f' output                | 160\
         3 | Identifier for the TESLA MAC           | see below\
         4 | Length of TESLA MAC output             | 80 (truncated)\
         5 | Start of session                       | in bytes\
         6 | Interval duration (in msec)            | in bytes\
         7 | Key disclosure delay                   | in bytes\
         8 | Key chain length (number of intervals) | in bytes\
         9 | Local timestamp media receiver         | see below\
\
   The time values stated in items 5 and 9 SHALL be transported in NTP-\
   UTC format, which is one of the three options described in Section\
   6.6 of [RFC3830].  A four-byte integer value for policy item 6 and a\
   two-byte integer value for policy item 7 are RECOMMENDED, carrying\
   interval duration and key disclosure delay.  Policy type 9 stated\
\
\
\
Fries & Tschofenig          Standards Track                     [Page 7]\
\
RFC 4442                  Bootstrapping TESLA                 March 2006\
\
\
   above is optional and SHOULD be used if the time synchronization\
   described in Section 4.3, point two, is used.  Otherwise, it SHOULD\
   be omitted.\
\
      For the PRF realizing F(x) and F'(x), a one-byte length is\
      sufficient.  The currently defined possible values are:\
\
        TESLA PRF F(x), F'(x)  | Value\
        ------------------------------\
        HMAC-SHA1              |  0\
\
      For the TESLA MAC, a one-byte length is enough.\
      The currently defined possible values are:\
\
        TESLA MAC       | Value\
        -----------------------\
        HMAC-SHA1       |  0\
\
4.3.  Time Synchronization\
\
   MIKEY as well as TESLA require the time synchronization of the\
   communicating peers.  MIKEY requires time synchronization to provide\
   timestamp-based replay protection for the one-roundtrip\
   authentication and key exchange protocols.  TESLA, on the other hand,\
   needs this information to determine the clock drift between the\
   senders and the receivers in order to release the disclosed key\
   appropriately.  Two alternatives are available for time\
   synchronization:\
\
   1.  Usage of out-of-band synchronization using NTP [RFC1305].  This\
       approach is already recommended within [RFC3830].  The advantage\
       of this approach is the option to use the MIKEY key management\
       variants that perform within a half-roundtrip.  The disadvantage\
       is the required time synchronization via an additional protocol.\
\
   2.  [RFC4082] also sketches a possible inband synchronization in\
       Section 3.3.1.  This approach is summarized here in the context\
       of MIKEY.  Note that here the actual TESLA policy payload is\
       transmitted as part of the MIKEY responder message.\
\
       *  The data receiver, which would be the MIKEY initiator, sets\
          the local time parameter t_r and sends it as part of the\
          timestamp payload as described in [RFC3830].  This value t_r\
          needs to be stored locally.\
\
       *  Upon receipt of the MIKEY initiator message, the data sender\
          replies with the MIKEY responder message, setting the local\
          time stamp at data receiver (parameter 11) to the value t_r\
\
\
\
Fries & Tschofenig          Standards Track                     [Page 8]\
\
RFC 4442                  Bootstrapping TESLA                 March 2006\
\
\
          received in the MIKEY initiator message, and sets his local\
          time as a 64-bit UTC value t_s in the timestamp payload as\
          described in [RFC3830].\
\
           MIKEY initiator message\
           [MIKEY parameter incl. local timestamp (t_r)]\
           ------------------>\
\
           MIKEY responder message\
           [MIKEY parameter incl. local timestamp (t_s), TESLA policy\
            payload, received local time stamp t_r]\
           <------------------\
\
       *  Upon receiving the MIKEY responder message the data receiver\
          sets D_t = t_s - t_r + S, where S is an estimated bound on the\
          clock drift throughout the duration of the session.\
\
       This approach has the advantage that it does not require an\
       additional time synchronization protocol.  The disadvantage is\
       the necessity to perform a full MIKEY handshake, to enable\
       correct parameter transport.  Moreover this approach is direction\
       dependent, as it may only be applied if the media receiver is\
       also the MIKEY initiator.\
\
   Out-of-band synchronization using NTP (i.e., alternative 1) is the\
   RECOMMENDED approach for clock synchronization.  In scenarios where\
   the media receiver is also the MIKEY initiator piggybacking timestamp\
   information in MIKEY (i.e., alternative 2) MAY be used to allow for\
   inband determination of the clock drift between sender and receiver.\
\
\
\
\
\
\
\
\
\
\
\
\
\
\
\
\
\
\
\
\
\
\
Fries & Tschofenig          Standards Track                     [Page 9]\
\
RFC 4442                  Bootstrapping TESLA                 March 2006\
\
\
4.4.  Key Data Transport within MIKEY's General Extension Payload\
\
   The General Extensions Payload was defined to allow possible\
   extensions to MIKEY without the need for defining a completely new\
   payload each time.  This payload can be used in any MIKEY message and\
   is part of the authenticated/signed data part.\
\
    0                   1                   2                   3\
    0 1 2 3 4 5 6 7 8 9 0 1 2 3 4 5 6 7 8 9 0 1 2 3 4 5 6 7 8 9 0 1\
   +-+-+-+-+-+-+-+-+-+-+-+-+-+-+-+-+-+-+-+-+-+-+-+-+-+-+-+-+-+-+-+-+\
   ! Next payload  ! Type          ! Length                        !\
   +-+-+-+-+-+-+-+-+-+-+-+-+-+-+-+-+-+-+-+-+-+-+-+-+-+-+-+-+-+-+-+-+\
   ! Data                                                          ~\
   +-+-+-+-+-+-+-+-+-+-+-+-+-+-+-+-+-+-+-+-+-+-+-+-+-+-+-+-+-+-+-+-+\
\
      *  Next payload (8 bits):\
         Identifies the payload following this payload.\
\
      *  Type (8 bits):\
         Identifies the type of general payload.\
         MIKEY already defines the values 0 and 1.\
         This document introduces a new value (2).\
\
         Type          | Value | Comments\
         ----------------------------------------------------\
         Vendor ID     |     0 | Vendor specific byte string\
         SDP IDs       |     1 | List of SDP key mgmt IDs\
         TESLA I-Key   |     2 | TESLA initial key\
\
      *  Length (16 bits):\
         The length in bytes of the Data field.\
\
      *  Data (variable length):\
         The general payload data.\
\
\
\
\
\
\
\
\
\
\
\
\
\
\
\
\
\
Fries & Tschofenig          Standards Track                    [Page 10]\
\
RFC 4442                  Bootstrapping TESLA                 March 2006\
\
\
5.  Security Considerations\
\
   The security properties of multi-media data in a multicast\
   environment depends on a number of building blocks.\
\
   SRTP-TESLA [RFC4383] describes extensions for SRTP [RFC3711] in order\
   to support TESLA [RFC4082] for source authentication in multicast\
   scenarios.  As such, security considerations described with TESLA\
   (see [PCST] and [RFC4082]), the TESLA SRTP mapping [RFC4383], and\
   SRTP [RFC3711] itself are relevant in this context.\
\
   Furthermore, since this document details bootstrapping of TESLA using\
   the Multimedia Internet Keying (MIKEY) [RFC3830] protocol, the\
   security considerations of MIKEY are applicable to this document.\
\
   As a summary, in order for a multi-media application to support\
   TESLA, the following protocol interactions (in relationship to this\
   document) are necessary:\
\
   o  MIKEY [RFC3830] is executed between the desired entities to\
      perform authentication and a secure distribution of keying\
      material.  In order to subsequently use TESLA, the parameters\
      described in this document are distributed using MIKEY.  MIKEY\
      itself uses another protocol for parameter transport, namely, the\
      Session Description Protocol (SDP) [RFC2327].  SDP might again be\
      used within Session Initiation Protocol (SIP, [RFC3261]) to set up\
      a session between the desired entities.\
\
   o  After the algorithms, parameters, and session keys are available\
      at the respective communication entities, data traffic protection\
      via SRTP-TESLA [RFC4383] can be used.  SRTP-TESLA itself applies\
      TESLA to the SRTP protocol, and as such the processing guidelines\
      of TESLA need to be followed.\
\
5.1.  Man-in-the-Middle Attack\
\
   Threat:\
\
      The exchange of security-related parameters and algorithms without\
      mutual authentication of the two peers can allow an adversary to\
      perform a man-in-the-middle attack.  The mechanisms described in\
      this document do not themselves provide such an authentication and\
      integrity protection.\
\
   Countermeasures:\
\
      Throughout the document, it is assumed that the parameter exchange\
      is secured using another protocol, i.e., the exchange parameters\
\
\
\
Fries & Tschofenig          Standards Track                    [Page 11]\
\
RFC 4442                  Bootstrapping TESLA                 March 2006\
\
\
      and algorithms are part of a authentication and key exchange\
      protocol (namely, MIKEY).  Source authentication of group and\
      multicast communication cannot be provided for the data traffic if\
      the prior signaling exchange did not provide facilities to\
      authenticate the source.  Using an authentication protocol that\
      does not provide session keys as part of a successful protocol\
      exchange will make it impossible to derive the necessary\
      parameters required by TESLA.  MIKEY provides session key\
      establishment.  Additionally, the exchange of parameters and\
      algorithms MUST be authenticated and integrity protected.  The\
      security protection of the parameter exchange needs to provide the\
      same level or a higher level of security.\
\
5.2.  Downgrading Attack\
\
   Threat:\
\
      The exchange of security-related parameters and algorithms is\
      always subject to downgrading whereby an adversary modifies some\
      (or all) of the provided parameters.  For example, a few\
      parameters require that a supported hash algorithm be listed.  To\
      mount an attack, the adversary has to modify the list of provided\
      algorithms and to select the weakest one.\
\
   Countermeasures:\
\
      TESLA parameter bootstrapping MUST be integrity protected to\
      prevent modification of the parameters and their values.\
      Moreover, since unmodified parameters from an unknown source are\
      not useful, authentication MUST be provided.  This functionality\
      is not provided by mechanisms described in this document.\
      Instead, the capabilities of the underlying authentication and key\
      exchange protocol (MIKEY) are reused for this purpose.\
\
5.3.  Denial of Service Attack\
\
   Threat:\
\
      An adversary might want to modify parameters exchanged between the\
      communicating entities in order to establish different state\
      information at the respective communication entities.  For\
      example, an adversary might want to modify the key disclosure\
      delay or the interval duration in order to disrupt the\
      communication at a later state since the TESLA algorithm assumes\
      that the participating communication entities know the same\
      parameter set.\
\
\
\
\
\
Fries & Tschofenig          Standards Track                    [Page 12]\
\
RFC 4442                  Bootstrapping TESLA                 March 2006\
\
\
   Countermeasures:\
\
      The exchanged parameters and the parameters and algorithms MUST be\
      integrity protected to allow the recipient to detect whether an\
      adversary attempted to modify the exchanged information.\
      Authentication and key exchange algorithms provided by MIKEY offer\
      this protection.\
\
5.4.  Replay Attack\
\
   Threat:\
\
      An adversary who is able to eavesdrop on one or multiple protocol\
      exchanges (MIKEY exchanges with the parameters described in this\
      document) might be able to replay the payloads in a later protocol\
      exchange.  If the recipients accept the parameters and algorithms\
      (or even the messages that carry these payloads), then a denial of\
      service, downgrading, or a man-in-the-middle attack might be the\
      consequence (depending on the entire set of replayed attributes\
      and messages).\
\
   Countermeasures:\
\
      In order to prevent replay attacks, a freshness guarantee MUST be\
      provided.  As such, the TESLA bootstrapping message exchange MUST\
      be unique and fresh, and the corresponding authentication and key\
      exchange protocol MUST provide the same properties.  In fact, it\
      is essential to derive a unique and fresh session key as part of\
      the authentication and key exchange protocol run that MUST be\
      bound to the protocol session.  This includes the exchanged\
      parameters.\
\
5.5.  Traffic Analysis\
\
   Threat:\
\
      An adversary might be able to learn parameters and algorithms if\
      he is located along the signaling path.  This information can then\
      later be used to mount attacks against the end-to-end multimedia\
      communication.  In some high-security and military environments,\
      it might even be desirable not to reveal information about the\
      used parameters to make it more difficult to launch an attack.\
\
   Countermeasures:\
\
      Confidentiality protection can be provided by a subset of the\
      available MIKEY authentication and key exchange protocols, namely,\
      those providing public key encryption and symmetric key\
\
\
\
Fries & Tschofenig          Standards Track                    [Page 13]\
\
RFC 4442                  Bootstrapping TESLA                 March 2006\
\
\
      encryption.  The initial hash key, which is also one of the TESLA\
      bootstrapping parameters, does not require confidentiality\
      protection due to the properties of a hash chain.\
\
6.  IANA Considerations\
\
   This document requires an IANA registration for the following\
   attributes.  The registries are provided by MIKEY [RFC3830].\
\
   Prot Type:\
\
      This attribute specifies the protocol type for the security\
      protocol as described in Section 4.1.\
\
   Type:\
\
      Identifies the type of the general payload.  The General\
      Extensions Payload was defined to allow possible extensions to\
      MIKEY without the need for defining a completely new payload each\
      time.  Section 4.4 describes this attribute in more detail.\
\
   Following the policies outlined in [RFC3830], the values in the range\
   up to 240 (including 240) for the above attributes are assigned after\
   expert review by the MSEC working group or its designated successor.\
   The values in the range from 241 to 255 are reserved for private use.\
\
   The IANA has added the following attributes and their respective\
   values to an existing registry created in [RFC3830]:\
\
   Prot Type:\
\
            Prot Type     | Value | Description\
            -----------------------------------------------------\
            TESLA         |     1 | TESLA as a security protocol\
\
   The value of 1 for the 'Prot Type' must be added to the 'Prot type'\
   registry created by [RFC3830].\
\
   Type:\
\
            Type          | Value | Description\
            -------------------------------------------\
            TESLA I-Key   |     2 | TESLA initial key\
\
   The value of 2 for the 'Type' must be added to the 'Type' registry\
   created by [RFC3830].  The values of 0 and 1 are already registered\
   in [RFC3830].\
\
\
\
\
Fries & Tschofenig          Standards Track                    [Page 14]\
\
RFC 4442                  Bootstrapping TESLA                 March 2006\
\
\
   Also, the IANA has created two new registries:\
\
   TESLA-PRF: Pseudo-random Function (PRF) used in the TESLA policy:\
\
      This attribute specifies values for pseudo-random functions used\
      in the TESLA policy (see Section 4.2).\
\
   TESLA-MAC: MAC Function used in TESLA:\
\
      This attribute specifies values for pseudo-random functions used\
      in the TESLA policy (see Section 4.2).\
\
   Following the policies outlined in [RFC2434], the values for the\
   TESLA-PRF and the TESLA-MAC registry in the range up to 240\
   (including 240) for the above attributes are assigned after expert\
   review by the MSEC working group or its designated successor.  The\
   values in the range from 241 to 255 are reserved for private use.\
\
   IANA has added the following values to the TESLA-PRF and the\
   TESLA-MAC registry:\
\
   TESLA-PRF:\
\
            PRF Function     | Value\
            --------------------------\
            HMAC-SHA1        |  0\
\
   TESLA-MAC:\
\
            MAC Function     | Value\
            --------------------------\
            HMAC-SHA1        |  0\
\
7.  Acknowledgements\
\
   The authors would like to thank Mark Baugher and Ran Canetti for the\
   discussions in context of time synchronization.  Additionally, we\
   would like to thank Lakshminath Dondeti, Russ Housley, and Allison\
   Mankin for their document reviews and for their guidance.\
\
\
\
\
\
\
\
\
\
\
\
\
Fries & Tschofenig          Standards Track                    [Page 15]\
\
RFC 4442                  Bootstrapping TESLA                 March 2006\
\
\
8.  References\
\
8.1.  Normative References\
\
   [RFC2119]  Bradner, S., "Key words for use in RFCs to Indicate\
              Requirement Levels", BCP 14, RFC 2119, March 1997.\
\
   [RFC2434]  Narten, T. and H. Alvestrand, "Guidelines for Writing an\
              IANA Considerations Section in RFCs", BCP 26, RFC 2434,\
              October 1998.\
\
   [RFC3830]  Arkko, J., Carrara, E., Lindholm, F., Naslund, M., and K.\
              Norrman, "MIKEY: Multimedia Internet KEYing", RFC 3830,\
              August 2004.\
\
   [RFC4082]  Perrig, A., Song, D., Canetti, R., Tygar, J., and B.\
              Briscoe, "Timed Efficient Stream Loss-Tolerant\
              Authentication (TESLA): Multicast Source Authentication\
              Transform Introduction", RFC 4082, June 2005.\
\
   [RFC4383]  Baugher, M. and E. Carrara, "The Use of Timed Efficient\
              Stream Loss-Tolerant Authentication (TESLA) in the Secure\
              Real-time Transport Protocol (SRTP)", RFC 4383,\
              February 2006.\
\
8.2.  Informative References\
\
   [DHHMAC]   Euchner, M., "HMAC-authenticated Diffie-Hellman for\
              MIKEY", Work in Progress, April 2005.\
\
   [PCST]     Perrig, A., Canetti, R., Song, D., and D. Tygar,\
              "Efficient and Secure Source Authentication for\
              Multicast", in Proc. of Network and Distributed System\
              Security Symposium NDSS 2001, pp. 35-46, 2001.\
\
   [RFC1305]  Mills, D., "Network Time Protocol (Version 3)\
              Specification, Implementation", RFC 1305, March 1992.\
\
   [RFC2327]  Handley, M. and V. Jacobson, "SDP: Session Description\
              Protocol", RFC 2327, April 1998.\
\
   [RFC3261]  Rosenberg, J., Schulzrinne, H., Camarillo, G., Johnston,\
              A., Peterson, J., Sparks, R., Handley, M., and E.\
              Schooler, "SIP: Session Initiation Protocol", RFC 3261,\
              June 2002.\
\
\
\
\
\
\
Fries & Tschofenig          Standards Track                    [Page 16]\
\
RFC 4442                  Bootstrapping TESLA                 March 2006\
\
\
   [RFC3711]  Baugher, M., McGrew, D., Naslund, M., Carrara, E., and K.\
              Norrman, "The Secure Real-time Transport Protocol (SRTP)",\
              RFC 3711, March 2004.\
\
   [RSA-R]    Ignjatic, D., "An additional mode of key distribution in\
              MIKEY: MIKEY-RSA-R", Work in Progress, February 2006.\
\
Authors' Addresses\
\
   Steffen Fries\
   Siemens\
   Otto-Hahn-Ring 6\
   Munich, Bavaria  81739\
   Germany\
\
   EMail: steffen.fries@siemens.com\
\
\
   Hannes Tschofenig\
   Siemens\
   Otto-Hahn-Ring 6\
   Munich, Bavaria  81739\
   Germany\
\
   EMail: Hannes.Tschofenig@siemens.com\
\
\
\
\
\
\
\
\
\
\
\
\
\
\
\
\
\
\
\
\
\
\
\
\
\
\
Fries & Tschofenig          Standards Track                    [Page 17]\
\
RFC 4442                  Bootstrapping TESLA                 March 2006\
\
\
Full Copyright Statement\
\
   Copyright (C) The Internet Society (2006).\
\
   This document is subject to the rights, licenses and restrictions\
   contained in BCP 78, and except as set forth therein, the authors\
   retain all their rights.\
\
   This document and the information contained herein are provided on an\
   "AS IS" basis and THE CONTRIBUTOR, THE ORGANIZATION HE/SHE REPRESENTS\
   OR IS SPONSORED BY (IF ANY), THE INTERNET SOCIETY AND THE INTERNET\
   ENGINEERING TASK FORCE DISCLAIM ALL WARRANTIES, EXPRESS OR IMPLIED,\
   INCLUDING BUT NOT LIMITED TO ANY WARRANTY THAT THE USE OF THE\
   INFORMATION HEREIN WILL NOT INFRINGE ANY RIGHTS OR ANY IMPLIED\
   WARRANTIES OF MERCHANTABILITY OR FITNESS FOR A PARTICULAR PURPOSE.\
\
Intellectual Property\
\
   The IETF takes no position regarding the validity or scope of any\
   Intellectual Property Rights or other rights that might be claimed to\
   pertain to the implementation or use of the technology described in\
   this document or the extent to which any license under such rights\
   might or might not be available; nor does it represent that it has\
   made any independent effort to identify any such rights.  Information\
   on the procedures with respect to rights in RFC documents can be\
   found in BCP 78 and BCP 79.\
\
   Copies of IPR disclosures made to the IETF Secretariat and any\
   assurances of licenses to be made available, or the result of an\
   attempt made to obtain a general license or permission for the use of\
   such proprietary rights by implementers or users of this\
   specification can be obtained from the IETF on-line IPR repository at\
   http://www.ietf.org/ipr.\
\
   The IETF invites any interested party to bring to its attention any\
   copyrights, patents or patent applications, or other proprietary\
   rights that may cover technology that may be required to implement\
   this standard.  Please address the information to the IETF at\
   ietf-ipr@ietf.org.\
\
Acknowledgement\
\
   Funding for the RFC Editor function is provided by the IETF\
   Administrative Support Activity (IASA).\
\
\
\
\
\
\
\
Fries & Tschofenig          Standards Track                    [Page 18]\
\

doc 6
  field 0
    name titolo
    type string
    value rfc4445.txt
  field 1
    name contenuto
    type string
    value \
\
\
\
\
\
Network Working Group                                           J. Welch\
Request for Comments: 4445                        IneoQuest Technologies\
Category: Informational                                         J. Clark\
                                                           Cisco Systems\
                                                              April 2006\
\
\
                 A Proposed Media Delivery Index (MDI)\
\
Status of This Memo\
\
   This memo provides information for the Internet community.  It does\
   not specify an Internet standard of any kind.  Distribution of this\
   memo is unlimited.\
\
Copyright Notice\
\
   Copyright (C) The Internet Society (2006).\
\
IESG Note\
\
   This RFC is not a candidate for any level of Internet Standard.\
   There are IETF standards which are highly applicable to the space\
   defined by this document as its applicability, in particular, RFCs\
   3393 and 3611, and there is ongoing IETF work in these areas as well.\
   The IETF also notes that the decision to publish this RFC is not\
   based on IETF review for such things as security, congestion control,\
   MIB fitness, or inappropriate interaction with deployed protocols.\
   The RFC Editor has chosen to publish this document at its discretion.\
   Readers of this document should exercise caution in evaluating its\
   value for implementation and deployment.  See RFC 3932 for more\
   information.\
\
Abstract\
\
   This memo defines a Media Delivery Index (MDI) measurement that can\
   be used as a diagnostic tool or a quality indicator for monitoring a\
   network intended to deliver applications such as streaming media,\
   MPEG video, Voice over IP, or other information sensitive to arrival\
   time and packet loss.  It provides an indication of traffic jitter, a\
   measure of deviation from nominal flow rates, and a data loss\
   at-a-glance measure for a particular flow.  For instance, the MDI may\
   be used as a reference in characterizing and comparing networks\
   carrying UDP streaming media.\
\
   The MDI measurement defined in this memo is intended for Information\
   only.\
\
\
\
\
Welch & Clark                Informational                      [Page 1]\
\
RFC 4445         A Proposed Media Delivery Index (MDI)        April 2006\
\
\
1.  Introduction\
\
   There has been considerable progress over the last several years in\
   the development of methods to provide for Quality of Service (QoS)\
   over packet-switched networks to improve the delivery of streaming\
   media and other time-sensitive and packet-loss-sensitive applications\
   such as [i1], [i5], [i6], [i7].  QoS is required for many practical\
   networks involving applications such as video transport to assure the\
   availability of network bandwidth by providing upper limits on the\
   number of flows admitted to a network, as well as to bound the packet\
   jitter introduced by the network.  These bounds are required to\
   dimension a receiver`s buffer to display the video properly in real\
   time without buffer overflow or underflow.\
\
   Now that large-scale implementations of such networks based on RSVP\
   and Diffserv are undergoing trials [i3] and being specified by major\
   service providers for the transport of streaming media such as MPEG\
   video [i4], there is a need to diagnose issues easily and to monitor\
   the real-time effectiveness of networks employing these QoS methods\
   or to assess whether they are required.  Furthermore, due to the\
   significant installed base of legacy networks without QoS methods, a\
   delivery system`s transitional solution may be composed of networks\
   with and without these methods, thus increasing the difficulty in\
   characterizing the dynamic behavior of these networks.\
\
   The purpose of this memo is to describe a set of measurements that\
   can be used to derive a Media Delivery Index (MDI) that indicates the\
   instantaneous and longer-term behavior of networks carrying streaming\
   media such as MPEG video.\
\
   While this memo addresses monitoring MPEG Transport Stream (TS)\
   packets [i8] over UDP, the general approach is expected to be\
   applicable to other streaming media and protocols.  The approach is\
   applicable to both constant and variable bit rate streams though the\
   variable bit rate case may be somewhat more difficult to calculate.\
   This document focuses on the constant bit rate case as the example to\
   describe the measurement, but as long as the dynamic bit rate of the\
   encoded stream can be determined (the "drain rate" as described below\
   in Section 3), then the MDI provides the measurement of network-\
   induced cumulative jitter.  Suggestions and direction for calculation\
   of MDI for a variable bit rate encoded stream may be the subject of a\
   future document.\
\
   Network packet delivery time variation and various statistics to\
   characterize the same are described in a generic approach in [i10].\
   The approach is capable of being parameterized for various purposes\
   with the intent of defining a flexible, customizable definition that\
   can be applied to a wide range of applications and further\
\
\
\
Welch & Clark                Informational                      [Page 2]\
\
RFC 4445         A Proposed Media Delivery Index (MDI)        April 2006\
\
\
   experimentation.  Other approaches to characterizing jitter behavior\
   are also captured such as in [i12].  A wide-ranging report format\
   [i11] has been described to convey information including jitter for\
   use with the RTP Control Protocol (RTCP) [i12].  The MDI is instead\
   intended to specifically address the need for a scalable,\
   economical-to-compute metric that characterizes network impairments\
   that may be imposed on streaming media, independent of control plane\
   or measurement transport protocol or stream encapsulation protocol.\
   It is a targeted metric for use in production networks carrying large\
   numbers of streams for the purpose of monitoring the network quality\
   of the flows or for other applications intended to analyze large\
   numbers of streams susceptible to IP network device impairments.  An\
   example application is the burgeoning deployments of Internet\
   Protocol Television (IPTV) by cable and telecommunication service\
   providers.  As described below, MDI provides for a readily scalable\
   per-stream measure focused on loss and the cumulative effects of\
   jitter.\
\
2.  Media Delivery Index Overview\
\
   The MDI provides a relative indicator of needed buffer depths at the\
   consumer node due to packet jitter as well as an indication of lost\
   packets.  By probing a streaming media service network at various\
   nodes and under varying load conditions, it is possible to quickly\
   identify devices or locales that introduce significant jitter or\
   packet loss to the packet stream.  By monitoring a network\
   continuously, deviations from nominal jitter or loss behavior can be\
   used to indicate an impending or ongoing fault condition such as\
   excessive load.  It is believed that the MDI provides the necessary\
   information to detect all network-induced impairments for streaming\
   video or voice-over-IP applications.  Other parameters may be\
   required to troubleshoot and correct the impairments.\
\
   The MDI is updated at the termination of selected time intervals\
   spanning multiple packets that contain the streaming media (such as\
   transport stream packets in the MPEG-2 case).  The Maximums and\
   Minimums of the MDI component values are captured over a measurement\
   time.  The measurement time may range from just long enough to\
   capture an anticipated network anomaly during a troubleshooting\
   exercise to indefinitely long for a long-term monitoring or logging\
   application.  The Maximums and Minimums may be obtained by sampling\
   the measurement with adequate frequency.\
\
\
\
\
\
\
\
\
\
Welch & Clark                Informational                      [Page 3]\
\
RFC 4445         A Proposed Media Delivery Index (MDI)        April 2006\
\
\
3.  Media Delivery Index Components\
\
   The MDI consists of two components:  the Delay Factor (DF) and the\
   Media Loss Rate (MLR).\
\
3.1.  Delay Factor\
\
   The Delay Factor is the maximum difference, observed at the end of\
   each media stream packet, between the arrival of media data and the\
   drain of media data.  This assumes the drain rate is the nominal\
   constant traffic rate for constant bit rate streams or the piece-wise\
   computed traffic rate of variable rate media stream packet data.  The\
   "drain rate" here refers to the payload media rate; e.g., for a\
   typical 3.75 Mb/s MPEG video Transport Stream (TS), the drain rate is\
   3.75 Mb/s -- the rate at which the payload is consumed (displayed) at\
   a decoding node.  If, at the sample time, the number of bytes\
   received equals the number transmitted, the instantaneous flow rate\
   balance will be zero; however, the minimum DF will be a line packet's\
   worth of media data, as that is the minimum amount of data that must\
   be buffered.\
\
   The DF is the maximum observed value of the flow rate imbalance over\
   a calculation interval.  This buffered media data in bytes is\
   expressed in terms of how long, in milliseconds, it would take to\
   drain (or fill) this data at the nominal traffic rate to obtain the\
   DF.  Display of DF with a resolution of tenths of milliseconds is\
   recommended to provide adequate indication of stream variations for\
   monitoring and diagnostic applications for typical stream rates from\
   1 to 40 Mb/s.  The DF value must be updated and displayed at the end\
   of a selected time interval.  The selected time interval is chosen to\
   be long enough to sample a number of TS packets and will, therefore,\
   vary based on the nominal traffic rate.  For typical stream rates of\
   1 Mb/s and up, an interval of 1 second provides a long enough sample\
   time and should be included for all implementations.  The Delay\
   Factor indicates how long a data stream must be buffered (i.e.,\
   delayed) at its nominal bit rate to prevent packet loss.  This time\
   may also be seen as a measure of the network latency that must be\
   induced from buffering, which is required to accommodate stream\
   jitter and prevent loss.  The DF`s max and min over the measurement\
   period (multiple intervals) may also be displayed to show the worst\
   case arrival time deviation, or jitter, relative to the nominal\
   traffic rate in a measurement period.  It provides a dynamic flow\
   rate balance indication with its max and min showing the worst\
   excursions from balance.\
\
   The Delay Factor gives a hint of the minimum size of the buffer\
   required at the next downstream node.  As a stream progresses, the\
   variation of the Delay Factor indicates packet bunching or packet\
\
\
\
Welch & Clark                Informational                      [Page 4]\
\
RFC 4445         A Proposed Media Delivery Index (MDI)        April 2006\
\
\
   gaps (jitter).  Greater DF values also indicate that more network\
   latency is necessary to deliver a stream due to the need to pre-fill\
   a receive buffer before beginning the drain to guarantee no\
   underflow.  The DF comprises a fixed part based on packet size and a\
   variable part based on the buffer utilization of the various network\
   component switch elements that comprise the switched network\
   infrastructure [i2].\
\
   To further detail the calculation of DF, consider a virtual buffer VB\
   used to buffer received packets of a stream.  When a packet P(i)\
   arrives during a calculation interval, compute two VB values,\
   VB(i,pre) and VB(i,post), defined as:\
\
   VB(i,pre) = sum (Sj) - MR * Ti; where j=1..i-1\
   VB(i,post) = VB(i,pre) + Si\
\
   where Sj is the media payload size of the jth packet, Ti is the\
   relative time at which packet i arrives in the interval, and MR is\
   the nominal media rate.\
\
   VB(i,pre) is the Virtual Buffer size just before the arrival of P(i).\
   VB(i,post) is the Virtual Buffer size just after the arrival of P(i).\
\
   The initial condition of VB(0) = 0 is used at the beginning of each\
   measurement interval.  A measurement interval is defined from just\
   after the time of arrival of the last packet during a nominal period\
   (typically 1 second) as mentioned above to the time just after the\
   arrival of the last packet of the next nominal period.\
\
   During a measurement interval, if k packets are received, then there\
   are 2*k+1 VB values used in deriving VB(max) and VB(min).  After\
   determining VB(max) and VB(min) from the 2k+1 VB samples, DF for the\
   measurement interval is computed and displayed as:\
\
   DF = [VB(max) - VB(min)]/ MR\
\
   As noted above, a measurement interval of 1 second is typically used.\
   If no packets are received during an interval, the last DF calculated\
   during an interval in which packets did arrive is displayed.  The\
   time of arrival of the last previous packet is always retained for\
   use in calculating VB when the next packet arrives (even if the time\
   of the last received packet spans measurement intervals).  For the\
   first received measurement interval of a measurement period, no DF is\
   calculated; however, packet arrival times are recorded for use in\
   calculating VB during the following interval.\
\
\
\
\
\
\
Welch & Clark                Informational                      [Page 5]\
\
RFC 4445         A Proposed Media Delivery Index (MDI)        April 2006\
\
\
3.2.  Media Loss Rate\
\
   The Media Loss Rate is the count of lost or out-of-order flow packets\
   over a selected time interval, where the flow packets are packets\
   carrying streaming application information.  There may be zero or\
   more streaming packets in a single IP packet.  For example, it is\
   common to carry seven 188 Byte MPEG Transport Stream packets in an IP\
   packet.  In such a case, a single IP packet loss would result in 7\
   lost packets counted (if those 7 lost packets did not include null\
   packets).  Including out-of-order packets is important, as many\
   stream consumer-type devices do not attempt to reorder packets that\
   are received out of order.\
\
3.3.  Media Delivery Index\
\
   Combining the Delay Factor and Media Loss Rate quantities for\
   presentation results in the following MDI:\
\
                                  DF:MLR\
    Where:\
                          DF is the Delay Factor\
                        MLR is the Media Loss Rate\
\
   At a receiving node, knowing its nominal drain bit rate, the DF`s max\
   indicates the size of buffer required to accommodate packet jitter.\
   Or, in terms of Leaky Bucket [i9] parameters, DF indicates bucket\
   size b, expressed in time to transmit bucket traffic b, at the given\
   nominal traffic rate, r.\
\
3.4.  MDI Application Examples\
\
   If a known, well-characterized receive node is separated from the\
   data source by unknown or less well-characterized nodes such as\
   intermediate switch nodes, the MDI measured at intermediate data\
   links provides a relative indication of the behavior of upstream\
   traffic flows.  DF difference indications between one node and\
   another in a data stream for a given constant interval of calculation\
   can indicate local areas of traffic congestion or possibly\
   misconfigured QoS flow specification(s) leading to greater filling of\
   measurement point local device buffers, resultant flow rate\
   deviations, and possible data loss.\
\
\
\
\
\
\
\
\
\
\
Welch & Clark                Informational                      [Page 6]\
\
RFC 4445         A Proposed Media Delivery Index (MDI)        April 2006\
\
\
   For a given MDI, if DF is high and/or the DF Max-Min captured over a\
   significant measurement period of multiple intervals is high, jitter\
   has been detected but the longer-term, average flow rate may be\
   nominal.  This could be the result of a transient flow upset due to a\
   coincident traffic stream unrelated to the flow of interest causing\
   packet bunching.  A high DF may cause downstream buffer overflow or\
   underflow or unacceptable latency even in the absence of lost data.\
\
   Due to transient network failures or DF excursions, packets may be\
   lost within the network.  The MLR component of the MDI shows this\
   condition.\
\
   Through automated or manual flow detection and identification and\
   subsequent MDI calculations for real-time statistics on a flow, the\
   DF can indicate the dynamic deterioration or increasing burstiness of\
   a flow, which can be used to anticipate a developing network\
   operation problem such as transient oversubscription.  Such\
   statistics can be obtained for flows within network switches using\
   available switch cpu resources due to the minimal computational\
   requirements needed for small numbers of flows.  Statistics for all\
   flows present on, say, a gigabit Ethernet network, will likely\
   require dedicated hardware facilities, though these can be modest, as\
   buffer requirements and the required calculations per flow are\
   minimal.  By equipping network switches with MDI measurements, flow\
   impairment issues can quickly be identified, localized, and\
   corrected.  Until switches are so equipped with appropriate hardware\
   resources, dedicated hardware tools can provide supplemental switch\
   statistics by gaining access to switch flows via mirror ports, link\
   taps, or the like as a transition strategy.\
\
   The MDI figure can also be used to characterize a flow decoder's\
   acceptable performance.  For example, an MPEG decoder could be\
   characterized as tolerating a flow with a given maximum DF and MLR\
   for acceptable display performance (acceptable on-screen artifacts).\
   Network conditions such as Interior Gateway Protocol (IGP)\
   reconvergence time then might also be included in the flow tolerance\
   DF resulting in a higher-quality user experience.\
\
4.  Summary\
\
   The MDI combines the Delay Factor, which indicates potential for\
   impending data loss, and Media Loss Rate as the indicator of lost\
   data.  By monitoring the DF and MLR and their min and max excursions\
   over a measurement period and at multiple strategic locations in a\
   network, traffic congestion or device impairments may be detected and\
   isolated for a network carrying streaming media content.\
\
\
\
\
\
Welch & Clark                Informational                      [Page 7]\
\
RFC 4445         A Proposed Media Delivery Index (MDI)        April 2006\
\
\
5.  Security Considerations\
\
   The measurements identified in this document do not directly affect\
   the security of a network or user.  Actions taken in response to\
   these measurements that may affect the available bandwidth of the\
   network or the availability of a service is out of scope for this\
   document.\
\
   Performing the measurements described in this document only requires\
   examination of payload header information (such as MPEG transport\
   stream headers or RTP headers) to determine nominal stream bit rate\
   and sequence number information.  Content may be encrypted without\
   affecting these measurements.  Therefore, content privacy is not\
   expected to be a concern.\
\
6.  Informative References\
\
   [i1]  Braden, R., Zhang, L., Berson, S., Herzog, S., and S. Jamin,\
         "Resource ReSerVation Protocol (RSVP) -- Version 1 Functional\
         Specification", RFC 2205, September 1997.\
\
   [i2]  Partridge, C., "A Proposed Flow Specification", RFC 1363,\
         September 1992.\
\
   [i3]  R. Fellman, `Hurdles to Overcome for Broadcast Quality Video\
         Delivery over IP` VidTranS 2002.\
\
   [i4]  CableLabs `PacketCable Dynamic Quality-of-Service\
         Specification`, PKT-SP-DQOS-I06-030415, 2003.\
\
   [i5]  Shenker, S., Partridge, C., and R. Guerin, "Specification of\
         Guaranteed Quality of Service", RFC 2212, September 1997.\
\
   [i6]  Wroclawski, J., "Specification of the Controlled-Load Network\
         Element Service", RFC 2211, September 1997.\
\
   [i7]  Braden, R., Clark, D., and S. Shenker, "Integrated Services in\
         the Internet Architecture: an Overview", RFC 1633, June 1994.\
\
   [i8]  ISO/IEC 13818-1 (MPEG-2 Systems)\
\
   [i9]  V. Raisanen, "Implementing Service Quality in IP Networks",\
         John Wiley & Sons Ltd., 2003.\
\
   [i10] Demichelis, C. and P. Chimento, "IP Packet Delay Variation\
         Metric for IP Performance Metrics (IPPM)", RFC 3393, November\
         2002.\
\
\
\
\
Welch & Clark                Informational                      [Page 8]\
\
RFC 4445         A Proposed Media Delivery Index (MDI)        April 2006\
\
\
   [i11] Friedman, T., Caceres, R., and A. Clark, "RTP Control Protocol\
         Extended Reports (RTCP XR)", RFC 3611, November 2003.\
\
   [i12] Schulzrinne, H.,  Casner, S., Frederick, R., and V. Jacobson,\
         "RTP: A Transport Protocol for Real-Time Applications", STD 64,\
         RFC 3550, July 2003.\
\
7.  Acknowledgements\
\
   The authors gratefully acknowledge the contributions of Marc Todd and\
   Jesse Beeson of IneoQuest Technologies, Inc., Bill Trubey and John\
   Carlucci of Time Warner Cable, Nishith Sinha of Cox Communications,\
   Ken Chiquoine of SeaChange International, Phil Proulx of Bell Canada,\
   Dr Paul Stallard of TANDBERG Television, Gary Hughes of Broadbus\
   Technologies, Brad Medford of SBC Laboratories, John Roy of Adelphia\
   Communications, Cliff Mercer, PhD of Kasenna, Mathew Ho of Rogers\
   Cable, and Irl Duling of Optinel Systems for reviewing and evaluating\
   early versions of this document and implementations for MDI.\
\
Authors' Addresses\
\
   James Welch\
   IneoQuest Technologies, Inc\
   170 Forbes Blvd\
   Mansfield, Massachusetts 02048\
\
   Phone: 508 618 0312\
   EMail: Jim.Welch@ineoquest.com\
\
\
   James Clark\
   Cisco Systems, Inc\
   500 Northridge Road\
   Suite 800\
   Atlanta, Georgia 30350\
\
   Phone: 678 352 2726\
   EMail: jiclark@cisco.com\
\
\
\
\
\
\
\
\
\
\
\
\
\
Welch & Clark                Informational                      [Page 9]\
\
RFC 4445         A Proposed Media Delivery Index (MDI)        April 2006\
\
\
Full Copyright Statement\
\
   Copyright (C) The Internet Society (2006).\
\
   This document is subject to the rights, licenses and restrictions\
   contained in BCP 78 and at www.rfc-editor.org/copyright.html, and\
   except as set forth therein, the authors retain all their rights.\
\
   This document and the information contained herein are provided on an\
   "AS IS" basis and THE CONTRIBUTOR, THE ORGANIZATION HE/SHE REPRESENTS\
   OR IS SPONSORED BY (IF ANY), THE INTERNET SOCIETY AND THE INTERNET\
   ENGINEERING TASK FORCE DISCLAIM ALL WARRANTIES, EXPRESS OR IMPLIED,\
   INCLUDING BUT NOT LIMITED TO ANY WARRANTY THAT THE USE OF THE\
   INFORMATION HEREIN WILL NOT INFRINGE ANY RIGHTS OR ANY IMPLIED\
   WARRANTIES OF MERCHANTABILITY OR FITNESS FOR A PARTICULAR PURPOSE.\
\
Intellectual Property\
\
   The IETF takes no position regarding the validity or scope of any\
   Intellectual Property Rights or other rights that might be claimed to\
   pertain to the implementation or use of the technology described in\
   this document or the extent to which any license under such rights\
   might or might not be available; nor does it represent that it has\
   made any independent effort to identify any such rights.  Information\
   on the procedures with respect to rights in RFC documents can be\
   found in BCP 78 and BCP 79.\
\
   Copies of IPR disclosures made to the IETF Secretariat and any\
   assurances of licenses to be made available, or the result of an\
   attempt made to obtain a general license or permission for the use of\
   such proprietary rights by implementers or users of this\
   specification can be obtained from the IETF on-line IPR repository at\
   http://www.ietf.org/ipr.\
\
   The IETF invites any interested party to bring to its attention any\
   copyrights, patents or patent applications, or other proprietary\
   rights that may cover technology that may be required to implement\
   this standard.  Please address the information to the IETF at\
   ietf-ipr@ietf.org.\
\
Acknowledgement\
\
   Funding for the RFC Editor function is provided by the IETF\
   Administrative Support Activity (IASA).\
\
\
\
\
\
\
\
Welch & Clark                Informational                     [Page 10]\
\

doc 7
  field 0
    name titolo
    type string
    value rfc4450.txt
  field 1
    name contenuto
    type string
    value \
\
\
\
\
\
Network Working Group                                            E. Lear\
Request for Comments: 4450                            Cisco Systems GmbH\
Category: Informational                                    H. Alvestrand\
                                                           Cisco Systems\
                                                              March 2006\
\
\
 Getting Rid of the Cruft: Report from an Experiment in Identifying and\
               Reclassifying Obsolete Standards Documents\
\
Status of This Memo\
\
   This memo provides information for the Internet community.  It does\
   not specify an Internet standard of any kind.  Distribution of this\
   memo is unlimited.\
\
Copyright Notice\
\
   Copyright (C) The Internet Society (2006).\
\
Abstract\
\
   This memo documents an experiment to review and classify Proposed\
   Standards as not reflecting documented practice within the world\
   today.  The results identify a set of documents that were marked as\
   Proposed Standards that are now reclassified as Historic.\
\
Table of Contents\
\
   1. Introduction and History ........................................1\
   2. Bulk Decommissioning Procedure ..................................2\
   3. Input, Mailing list, Output, and Observations ...................2\
   4. Discussion ......................................................4\
   5. Next Steps ......................................................5\
   6. IANA Considerations .............................................6\
   7. Security Considerations .........................................6\
   8. Acknowledgements ................................................6\
   9. Normative References ............................................6\
\
1.  Introduction and History\
\
   RFC 2026, and RFC 1602 before it, specified timelines for review of\
   immature (draft or proposed) standards.  The purpose of such review\
   was to determine whether such documents should be advanced, retired,\
   or developed further [1].\
\
\
\
\
\
\
Lear & Alvestrand            Informational                      [Page 1]\
\
RFC 4450                     Cruft Removal                    March 2006\
\
\
   This procedure has never been followed in the history of the IETF.\
   Since this procedure has not been followed, members of the community\
   have suggested that the retiring of a document to Historic is a\
   significant event, which should be justified carefully -- leading to\
   the production of documents such as RFC 2556 (OSI Connectionless\
   Transport Services on top of UDP Applicability Statement for Historic\
    Status) and RFC 3166 (Request to Move RFC 1403 to Historic Status).\
\
   Such documents require significant time and effort on the part of\
   authors, area directors, and the RFC Editor.\
\
2.  Bulk Decommissioning Procedure\
\
   From the Fall of 2004 through the Spring of 2005, the authors\
   conducted an experiment to determine how many Proposed Standards\
   could be considered obsolete.  The experiment was operated as\
   follows:\
\
   o  Identify a group of documents that are standards.\
   o  Assume by default that each document will be retired.\
   o  Create a mailing list for discussion with a policy of open access.\
   o  Allow any document to be removed from the list of those to be\
      retired for virtually any reason, so long as a reason is provided.\
   o  Present the list to the working group, IETF, and IESG for review.\
   o  Revise list based on comments.\
   o  Write up results.\
\
   The initial intent of the authors was to present a list of documents\
   to be reclassified as Historic.  The NEWTRK working group supported\
   this view.  The IESG, and the IETF as a community, makes the final\
   decision.  We will discuss this further below.\
\
3.  Input, Mailing list, Output, and Observations\
\
   We started with our initial document set being all RFCs with numbers\
   less than 2000 and a status of Proposed Standard.  The input we used,\
   starting November 25, 2004, can be found in Appendix A.  There were\
   some 125 documents in all.\
\
   A mailing list, old-standards@alvestrand.no, was created to discuss\
   and remove candidates from this list.  A call for participation was\
   issued to the IETF-Announce list on or around the November 15, 2004.\
   There were 29 members of the mailing list.  Approximately 244\
   messages were sent to the list.  People were encouraged to consider\
   the question of whether or not an implementer would either write a\
   new implementation or maintain an existing one.\
\
\
\
\
\
Lear & Alvestrand            Informational                      [Page 2]\
\
RFC 4450                     Cruft Removal                    March 2006\
\
\
   After some months the list of documents to be considered was reduced\
   considerably.  This list was then forwarded to the IETF discussion\
   list on December 16, 2004, and to the NEWTRK working group list for\
   wider review.\
\
   During review, RFCs 1518 and 1519 were removed, based on the fact\
   that work is ongoing to revise them.  Similarly, RFCs 1381, 1382,\
   1471, 1472, 1473, 1582, 1598, and 1755 were removed based on the\
   belief that they were actively in use.  RFC 1584 was removed based on\
   an expected future dependency.\
\
   Here are the results:\
\
   RFC 1234 (Tunneling IPX Traffic through IP Networks)\
   RFC 1239 (Reassignment of Experimental MIBs to Standard MIBs)\
   RFC 1276 (Replication and Distributed Operations Extensions to\
            provide an Internet Directory Using X.500)\
   RFC 1285 (FDDI Management Information Base)\
   RFC 1314 (A File Format for the Exchange of Images in the Internet)\
   RFC 1328 (X.400 1988 to 1984 Downgrading)\
   RFC 1370 (Applicability Statement for OSPF)\
   RFC 1378 (The PPP AppleTalk Control Protocol (ATCP))\
   RFC 1397 (Default Route Advertisement in BGP2 and BGP3 Version of\
            the Border Gateway Protocol)\
   RFC 1414 (Identification MIB)\
   RFC 1415 (FTP-FTAM Gateway Specification)\
   RFC 1418 (SNMP over OSI)\
   RFC 1419 (SNMP over AppleTalk)\
   RFC 1421 (Privacy Enhancement for Internet Electronic Mail: Part I:\
            Message Encryption and Authentication Procedures)\
   RFC 1422 (Privacy Enhancement for Internet Electronic Mail: Part\
            II: Certificate-Based Key Management)\
   RFC 1423 (Privacy Enhancement for Internet Electronic Mail: Part\
            III: Algorithms, Modes, and Identifiers)\
   RFC 1424 (Privacy Enhancement for Internet Electronic Mail: Part\
            IV: Key Certification and Related Services)\
   RFC 1461 (SNMP MIB Extension for Multiprotocol Interconnect over\
            X.25)\
   RFC 1469 (IP Multicast over Token-Ring Local Area Networks)\
   RFC 1474 (The Definitions of Managed Objects for the Bridge Network\
            Control Protocol of the Point-to-Point Protocol)\
   RFC 1478 (An Architecture for Inter-Domain Policy Routing)\
   RFC 1479 (Inter-Domain Policy Routing Protocol Specification:\
            Version 1)\
   RFC 1494 (Equivalences between 1988 X.400 and RFC-822 Message\
            Bodies)\
   RFC 1496 (Rules for Downgrading Messages from X.400/88 to X.400/84)\
            when MIME Content-types Are Present in the Messages\
\
\
\
Lear & Alvestrand            Informational                      [Page 3]\
\
RFC 4450                     Cruft Removal                    March 2006\
\
\
   RFC 1502 (X.400 Use of Extended Character Sets)\
   RFC 1512 (FDDI Management Information Base)\
   RFC 1513 (Token Ring Extensions to the Remote Network Monitoring\
            MIB)\
   RFC 1525 (Definitions of Managed Objects for Source Routing\
            Bridges)\
   RFC 1552 (The PPP Internetworking Packet Exchange Control Protocol\
            (IPXCP))\
   RFC 1553 (Compressing IPX Headers over WAN Media (CIPX))\
   RFC 1648 (Postmaster Convention for X.400 Operations)\
   RFC 1666 (Definitions of Managed Objects for SNA NAUs using SMIv2)\
   RFC 1692 (Transport Multiplexing Protocol (TMux))\
   RFC 1696 (Modem Management Information Base (MIB) Using SMIv2)\
   RFC 1742 (AppleTalk Management Information Base II)\
   RFC 1747 (Definitions of Managed Objects for SNA Data Link Control\
            (SDLC) Using SMIv2)\
   RFC 1749 (IEEE 802.5 Station Source Routing MIB using SMIv2)\
   RFC 1763 (The PPP Banyan Vines Control Protocol (BVCP))\
   RFC 1764 (The PPP XNS IDP Control Protocol (XNSCP))\
   RFC 1828 (IP Authentication using Keyed MD5)\
   RFC 1835 (Architecture of the WHOIS++ Service)\
   RFC 1848 (MIME Object Security Services)\
   RFC 1913 (Architecture of the Whois++ Index Service)\
   RFC 1914 (How to Interact with a Whois++ Mesh)\
\
   One additional document, RFC 1829, the ESP DES-CBC transform, was\
   suggested for Historic status, but in this case, the group consensus\
   is that the community would benefit from a separate document\
   describing the security implications of using this algorithm.\
\
4.  Discussion\
\
   As one peruses this list one sees several classes of documents:\
\
   o  Multiprotocol functions for protocols that are obsolete, such as\
      Appletalk or X.400.\
   o  Protocols that were defined but not used, such as PEM or Whois++\
\
   In either case above, a judgment is necessary as to whether or not a\
   protocol is both in use and likely to be supported.  The parameters\
   of our experiment were sufficiently conservative to avoid cases where\
   protocols were likely to continue to be supported.  That is, anyone\
   could remove a document from the list for any reason.  In fact, in\
   some cases we may have been too conservative.  Thus, it is also worth\
   considering the categories of documents that were removed from the\
   list:\
\
\
\
\
\
Lear & Alvestrand            Informational                      [Page 4]\
\
RFC 4450                     Cruft Removal                    March 2006\
\
\
   o  specifications known to be in full use that should be considered\
      for advancement\
   o  specifications that are currently under review within the IETF\
      process\
   o  Specifications that were previously considered for deprecation and\
      rejected.\
\
   The last category is exclusive to telnet options, which were reviewed\
   in the late 1990s.  Arguably, such options should be reconsidered for\
   deprecation.  Realistically, nobody is going to develop a new version\
   of telnet that supports the TACACS option, for instance.\
   Nevertheless, as a first cut we were still left with 61 documents\
   that could be reclassified.\
\
   In at least one case, discussion of deprecation has spurred work on\
   documents.  For instance, there is a Classless Inter-Domain Routing\
   (CIDR) update in progress.\
\
5.  Next Steps\
\
   As we mention in the introduction, the current process requires\
   reconsideration of immature standards, and this review currently does\
   not occur.  This experiment has been an attempt at a procedure that\
   could ease that review.  The final step was working group\
   consideration of what to do next.  There were four options:\
\
   1.  Accept the results of this experiment, issue a last call, and\
       deprecate standards that remain on the list past last call.  This\
       is an aggressive approach that would preserve the intent of RFC\
       2026.\
   2.  Do not accept the results of this experiment and update RFC 2026\
       to indicate a new practice.\
   3.  Revise the procedure based on the results of this experiment,\
       based on feedback from the IESG.  This option might take into\
       account the different types of old standards as described above.\
   4.  Do nothing.  This would leave the IETF and the IESG practice\
       inconsistent with documented practice.\
\
   The working group chose the first option.  The RFC Editor is\
   requested to mark the above listed standards as Historic.\
\
   It should be pointed out that we only looked at proposed standards\
   and only those RFCs with numbers less than 2000.  Should either the\
   first or third of the above options be accepted, draft standards and\
   those older than several years should be considered.\
\
\
\
\
\
\
Lear & Alvestrand            Informational                      [Page 5]\
\
RFC 4450                     Cruft Removal                    March 2006\
\
\
   Finally, should NEWTRK deliver a new document classification system,\
   these documents may provide a basis for one or more new categories of\
   that.\
\
6.  IANA Considerations\
\
   The IANA databases contain references to many of these documents.\
   The documents are still the normative definitions for these values,\
   and the IANA databases do not contain information about the status of\
   the RFCs referred to.\
\
   Therefore, the IANA should not need to do anything based on this\
   document.\
\
7.  Security Considerations\
\
   Documents that have security problems may require special attention\
   and individual documents to indicate what concerns exist, and when or\
   in what ways an implementation can be deployed to alleviate concerns.\
\
8.  Acknowledgements\
\
   This experiment would have been completely useless without\
   participation of the members of the old-standards mailing list.  Most\
   notably, Pekka Savalo, Bob Braden, and John Klensin were very active\
   contributors to the discussions.\
\
9.  Normative References\
\
   [1]  Bradner, S., "The Internet Standards Process -- Revision 3", BCP\
        9, RFC 2026, October 1996.\
\
\
\
\
\
\
\
\
\
\
\
\
\
\
\
\
\
\
\
\
Lear & Alvestrand            Informational                      [Page 6]\
\
RFC 4450                     Cruft Removal                    March 2006\
\
\
Appendix A.  Input RFCs\
\
   RFC 0698 (Telnet Extended ASCII Option)\
   RFC 0726 (Remote Controlled Transmission and Echoing Telnet Option)\
   RFC 0727 (Telnet Logout Option)\
   RFC 0735 (Revised Telnet Byte Macro Option)\
   RFC 0736 (Telnet SUPDUP Option)\
   RFC 0749 (Telnet SUPDUP-Output Option)\
   RFC 0779 (Telnet send-location Option)\
   RFC 0885 (Telnet End of Record Option)\
   RFC 0927 (TACACS User Identification Telnet Option)\
   RFC 0933 (Output Marking Telnet Option)\
   RFC 0946 (Telnet Terminal Location Number Option)\
   RFC 0977 (Network News Transfer Protocol)\
   RFC 1041 (Telnet 3270 Regime Option)\
   RFC 1043 (Telnet Data Entry Terminal Option: DODIIS Implementation)\
   RFC 1053 (Telnet X.3 PAD Option)\
   RFC 1073 (Telnet Window sSize Option)\
   RFC 1079 (Telnet Terminal Speed Option)\
   RFC 1091 (Telnet Terminal-type Option)\
   RFC 1096 (Telnet X Display Location Option)\
   RFC 1144 (Compressing TCP/IP Headers for Low-speed Serial Links)\
   RFC 1195 (Use of OSI IS-IS for Routing in TCP/IP and Dual)\
   RFC 1234 (Tunneling IPX Traffic through IP Networks)\
   RFC 1239 (Reassignment of Experimental MIBs to Standard MIBs)\
   RFC 1256 (ICMP Router Discovery Messages)\
   RFC 1269 (Definitions of Managed Objects for the Border Gateway\
            Protocol: Version 3)\
   RFC 1274 (The COSINE and Internet X.500 Schema)\
   RFC 1276 (Replication and Distributed Operations Extensions to\
            Provide an Internet Directory Using X.500)\
   RFC 1277 (Encoding Network Addresses to Support Operation over Non-\
            OSI Lower Layers)\
   RFC 1285 (FDDI Management Information Base)\
   RFC 1314 (A File Format for the Exchange of Images in the Internet)\
   RFC 1323 (TCP Extensions for High Performance)\
   RFC 1328 (X.400 1988 to 1984 Downgrading)\
   RFC 1332 (The PPP Internet Protocol Control Protocol (IPCP))\
   RFC 1370 (Applicability Statement for OSPF)\
   RFC 1372 (Telnet Remote Flow Control Option)\
   RFC 1377 (The PPP OSI Network Layer Control Protocol (OSINLCP))\
   RFC 1378 (The PPP AppleTalk Control Protocol (ATCP))\
   RFC 1381 (SNMP MIB Extension for X.25 LAPB)\
   RFC 1382 (SNMP MIB Extension for the X.25 Packet Layer)\
   RFC 1397 (Default Route Advertisement in BGP2 and BGP3 Version of\
            the Border Gateway Protocol)\
   RFC 1413 (Identification Protocol)\
   RFC 1414 (Identification MIB)\
\
\
\
Lear & Alvestrand            Informational                      [Page 7]\
\
RFC 4450                     Cruft Removal                    March 2006\
\
\
   RFC 1415 (FTP-FTAM Gateway Specification)\
   RFC 1418 (SNMP over OSI)\
   RFC 1419 (SNMP over AppleTalk)\
   RFC 1420 (SNMP over IPX)\
   RFC 1421 (Privacy Enhancement for Internet Electronic Mail: Part I:\
            Message Encryption and Authentication Procedures)\
   RFC 1422 (Privacy Enhancement for Internet Electronic Mail: Part\
            II: Certificate-Based Key Management)\
   RFC 1423 (Privacy Enhancement for Internet Electronic Mail: Part\
            III: Algorithms, Modes, and Identifiers)\
   RFC 1424 (Privacy Enhancement for Internet Electronic Mail: Part\
            IV: Key Certification and Related Services)\
   RFC 1461 (SNMP MIB extension for Multiprotocol Interconnect over\
            X.25)\
   RFC 1469 (IP Multicast over Token-Ring Local Area Networks)\
   RFC 1471 (The Definitions of Managed Objects for the Link Control\
            Protocol of the Point-to-Point Protocol)\
   RFC 1472 (The Definitions of Managed Objects for the Security\
            Protocols of the Point-to-Point Protocol)\
   RFC 1473 (The Definitions of Managed Objects for the IP Network\
            Control Protocol of the Point-to-Point Protocol)\
   RFC 1474 (The Definitions of Managed Objects for the Bridge Network\
            Control Protocol of the Point-to-Point Protocol)\
   RFC 1478 (An Architecture for Inter-Domain Policy Routing)\
   RFC 1479 (Inter-Domain Policy Routing Protocol Specification:\
            Version 1)\
   RFC 1494 (Equivalences between 1988 X.400 and RFC-822 Message\
            Bodies)\
   RFC 1496 (Rules for Downgrading Messages from X.400/88 to X.400/84)\
   RFC 1502 (X.400 Use of Extended Character Sets)\
   RFC 1510 (The Kerberos Network Authentication Service (V5))\
   RFC 1512 (FDDI Management Information Base)\
   RFC 1513 (Token Ring Extensions to the Remote Network Monitoring\
            MIB)\
   RFC 1517 (Applicability Statement for the Implementation of\
            Classless Inter-Domain Routing (CIDR))\
   RFC 1518 (An Architecture for IP Address Allocation with CIDR)\
   RFC 1519 (Classless Inter-Domain Routing (CIDR): an Address\
            Assignment and Aggregation Strategy)\
   RFC 1525 (Definitions of Managed Objects for Source Routing\
            Bridges)\
   RFC 1552 (The PPP Internetworking Packet Exchange Control Protocol)\
   RFC 1553 (Compressing IPX Headers over WAN Media (CIPX))\
   RFC 1570 (PPP LCP Extensions)\
   RFC 1572 (Telnet Environment Option)\
   RFC 1582 (Extensions to RIP to Support Demand Circuits)\
   RFC 1584 (Multicast Extensions to OSPF)\
   RFC 1598 (PPP in X.25)\
\
\
\
Lear & Alvestrand            Informational                      [Page 8]\
\
RFC 4450                     Cruft Removal                    March 2006\
\
\
   RFC 1618 (PPP over ISDN)\
   RFC 1628 (UPS Management Information Base)\
   RFC 1648 (Postmaster Convention for X.400 Operations)\
   RFC 1663 (PPP Reliable Transmission)\
   RFC 1666 (Definitions of Managed Objects for SNA NAUs Using SMIv2)\
   RFC 1692 (Transport Multiplexing Protocol (TMux))\
   RFC 1696 (Modem Management Information Base (MIB) Using SMIv2)\
   RFC 1697 (Relational Database Management System (RDBMS) Management)\
   RFC 1731 (IMAP4 Authentication Mechanisms)\
   RFC 1734 (POP3 AUTHentication command)\
   RFC 1738 (Uniform Resource Locators (URL))\
   RFC 1740 (MIME Encapsulation of Macintosh Files - MacMIME)\
   RFC 1742 (AppleTalk Management Information Base II)\
   RFC 1747 (Definitions of Managed Objects for SNA Data Link Control)\
   RFC 1749 (IEEE 802.5 Station Source Routing MIB Using SMIv2)\
   RFC 1752 (The Recommendation for the IP Next Generation Protocol)\
   RFC 1755 (ATM Signaling Support for IP over ATM)\
   RFC 1763 (The PPP Banyan Vines Control Protocol (BVCP))\
   RFC 1764 (The PPP XNS IDP Control Protocol (XNSCP))\
   RFC 1767 (MIME Encapsulation of EDI Objects)\
   RFC 1793 (Extending OSPF to Support Demand Circuits)\
   RFC 1808 (Relative Uniform Resource Locators)\
   RFC 1812 (Requirements for IP Version 4 Routers)\
   RFC 1828 (IP Authentication using Keyed MD5)\
   RFC 1829 (The ESP DES-CBC Transform)\
   RFC 1831 (RPC: Remote Procedure Call Protocol Specification Version\
            2)\
   RFC 1833 (Binding Protocols for ONC RPC Version 2)\
   RFC 1835 (Architecture of the WHOIS++ Service)\
   RFC 1847 (Security Multiparts for MIME: Multipart/Signed and\
            Multipart/Encrypted)\
   RFC 1848 (MIME Object Security Services)\
   RFC 1913 (Architecture of the Whois++ Index Service)\
   RFC 1914 (How to Interact with a Whois++ Mesh)\
   RFC 1928 (SOCKS Protocol Version 5)\
   RFC 1929 (Username/Password Authentication for SOCKS V5)\
   RFC 1961 (GSS-API Authentication Method for SOCKS Version 5)\
   RFC 1962 (The PPP Compression Control Protocol (CCP))\
   RFC 1964 (The Kerberos Version 5 GSS-API Mechanism)\
   RFC 1968 (The PPP Encryption Control Protocol (ECP))\
   RFC 1973 (PPP in Frame Relay)\
   RFC 1982 (Serial Number Arithmetic)\
   RFC 1985 (SMTP Service Extension for Remote Message Queue Starting)\
   RFC 1995 (Incremental Zone Transfer in DNS)\
   RFC 1996 (A Mechanism for Prompt Notification of Zone Changes (DNS\
            NOTIFY))\
   RFC 1997 (BGP Communities Attribute)\
\
\
\
\
Lear & Alvestrand            Informational                      [Page 9]\
\
RFC 4450                     Cruft Removal                    March 2006\
\
\
Authors' Addresses\
\
   Eliot Lear\
   Cisco Systems GmbH\
   Glatt-com\
   Glattzentrum, ZH  CH-8301\
   Switzerland\
\
   Phone: +41 1 878 7525\
   EMail: lear@cisco.com\
\
\
   Harald Tveit Alvestrand\
   Cisco Systems\
   Weidemanns vei 27\
   7043 Trondheim\
   Norway\
\
   EMail: harald@alvestrand.no\
\
\
\
\
\
\
\
\
\
\
\
\
\
\
\
\
\
\
\
\
\
\
\
\
\
\
\
\
\
\
\
\
Lear & Alvestrand            Informational                     [Page 10]\
\
RFC 4450                     Cruft Removal                    March 2006\
\
\
Full Copyright Statement\
\
   Copyright (C) The Internet Society (2006).\
\
   This document is subject to the rights, licenses and restrictions\
   contained in BCP 78, and except as set forth therein, the authors\
   retain all their rights.\
\
   This document and the information contained herein are provided on an\
   "AS IS" basis and THE CONTRIBUTOR, THE ORGANIZATION HE/SHE REPRESENTS\
   OR IS SPONSORED BY (IF ANY), THE INTERNET SOCIETY AND THE INTERNET\
   ENGINEERING TASK FORCE DISCLAIM ALL WARRANTIES, EXPRESS OR IMPLIED,\
   INCLUDING BUT NOT LIMITED TO ANY WARRANTY THAT THE USE OF THE\
   INFORMATION HEREIN WILL NOT INFRINGE ANY RIGHTS OR ANY IMPLIED\
   WARRANTIES OF MERCHANTABILITY OR FITNESS FOR A PARTICULAR PURPOSE.\
\
Intellectual Property\
\
   The IETF takes no position regarding the validity or scope of any\
   Intellectual Property Rights or other rights that might be claimed to\
   pertain to the implementation or use of the technology described in\
   this document or the extent to which any license under such rights\
   might or might not be available; nor does it represent that it has\
   made any independent effort to identify any such rights.  Information\
   on the procedures with respect to rights in RFC documents can be\
   found in BCP 78 and BCP 79.\
\
   Copies of IPR disclosures made to the IETF Secretariat and any\
   assurances of licenses to be made available, or the result of an\
   attempt made to obtain a general license or permission for the use of\
   such proprietary rights by implementers or users of this\
   specification can be obtained from the IETF on-line IPR repository at\
   http://www.ietf.org/ipr.\
\
   The IETF invites any interested party to bring to its attention any\
   copyrights, patents or patent applications, or other proprietary\
   rights that may cover technology that may be required to implement\
   this standard.  Please address the information to the IETF at\
   ietf-ipr@ietf.org.\
\
Acknowledgement\
\
   Funding for the RFC Editor function is provided by the IETF\
   Administrative Support Activity (IASA).\
\
\
\
\
\
\
\
Lear & Alvestrand            Informational                     [Page 11]\
\

doc 8
  field 0
    name titolo
    type string
    value rfc4446.txt
  field 1
    name contenuto
    type string
    value \
\
\
\
\
\
Network Working Group                                         L. Martini\
Request for Comments: 4446                            Cisco Systems Inc.\
BCP: 116                                                      April 2006\
Category: Best Current Practice\
\
\
     IANA Allocations for Pseudowire Edge to Edge Emulation (PWE3)\
\
Status of This Memo\
\
   This document specifies an Internet Best Current Practices for the\
   Internet Community, and requests discussion and suggestions for\
   improvements.  Distribution of this memo is unlimited.\
\
Copyright Notice\
\
   Copyright (C) The Internet Society (2006).\
\
Abstract\
\
   This document allocates the fixed pseudowire identifier and other\
   fixed protocol values for protocols that have been defined in the\
   Pseudo Wire Edge to Edge (PWE3) working group.  Detailed IANA\
   allocation instructions are also included in this document.\
\
Table of Contents\
\
   1. Introduction ....................................................2\
   2. Specification of Requirements ...................................2\
   3. IANA Considerations .............................................2\
      3.1. Expert Review Directives ...................................2\
      3.2. MPLS Pseudowire Type .......................................3\
      3.3. Interface Parameters Sub-TLV Type ..........................4\
      3.4. Attachment Identifiers .....................................5\
           3.4.1. Attachment Individual Identifier Type ...............5\
           3.4.2. Attachment Group Identifier (AGI) Type ..............5\
      3.5. Pseudowire Status ..........................................6\
      3.6. PW Associated Channel Type .................................6\
   4. Security Considerations .........................................7\
   5. References ......................................................7\
      5.1. Normative References .......................................7\
      5.2. Informative References .....................................7\
\
\
\
\
\
\
\
\
\
Martini                  Best Current Practice                  [Page 1]\
\
RFC 4446               IANA Allocations for PWE3              April 2006\
\
\
1.  Introduction\
\
   Most of the new IANA registries and respective IANA-allocation\
   processes for protocols defined in the PWE3 IETF working group can be\
   found in this document.  The IANA registries defined here are in\
   general subdivided into three main ranges: a range to be allocated by\
   IETF consensus according to [RFC2434], a range to be allocated by the\
   expert review process according to [RFC2434], and a range to be\
   allocated on a first come, first served basis that is reserved for\
   vendor proprietary allocations.  Note that vendor proprietary types\
   MUST NOT be registered for IETF standards or extensions thereof,\
   whether they are still in development or already completed.\
\
2.  Specification of Requirements\
\
   The key words "MUST", "MUST NOT", "REQUIRED", "SHALL", "SHALL NOT",\
   "SHOULD", "SHOULD NOT", "RECOMMENDED", "MAY", and "OPTIONAL" in this\
   document are to be interpreted as described in [RFC2119].\
\
3.  IANA Considerations\
\
   IANA has created several registries as described in the following\
   paragraphs.  Each of these registries contains numeric values used to\
   identify data types.  In each of these registries, the value of 0 is\
   reserved and MUST not be used.\
\
3.1.  Expert Review Directives\
\
   Throughout this document, allocation procedures for several\
   registries call for an expert review process according to [RFC2434].\
   The expert should consider the following points:\
\
      *  Duplication of code point allocations should be avoided.\
\
      *  A brief, clear description of the code point allocation\
         requested should be provided.\
\
      *  The type allocation requested should be appropriate for the\
         particular requested value range in the registry.\
\
   The expert reviewing the request MUST approve or disapprove the\
   request within 10 business days from when he or she received the\
   expert review request.\
\
\
\
\
\
\
\
\
Martini                  Best Current Practice                  [Page 2]\
\
RFC 4446               IANA Allocations for PWE3              April 2006\
\
\
3.2.  MPLS Pseudowire Type\
\
   IANA has set up the registry of "MPLS Pseudowire Type".  This type\
   has 15-bit values.  PW Type values 1 through 30 are specified in this\
   document, and PW Type values 31 through 1024 are to be assigned by\
   IANA, using the "Expert Review" policy defined in [RFC2434].  PW Type\
   values 1025 through 4096 and 32767 are to be allocated using the IETF\
   consensus policy defined in [RFC2434].  PW Type values 4097 through\
   32766 are reserved for vendor-proprietary extensions and are to be\
   assigned by IANA, using the "First Come First Served" policy defined\
   in [RFC2434].  A Pseudowire Type description is required for any\
   assignment from this registry.  Additionally, for the vendor-\
   proprietary extensions range, a citation of a person or company name\
   is also required.  A document reference should also be provided.\
\
   Initial Pseudowire Type value allocations are specified below:\
\
   PW type Description                                      Reference\
   ===================================================================\
   0x0001  Frame Relay DLCI ( Martini Mode )                [FRAME]\
   0x0002  ATM AAL5 SDU VCC transport                       [ATM]\
   0x0003  ATM transparent cell transport                   [ATM]\
   0x0004  Ethernet Tagged Mode                             [ETH]\
   0x0005  Ethernet                                         [ETH]\
   0x0006  HDLC                                             [PPPHDLC]\
   0x0007  PPP                                              [PPPHDLC]\
   0x0008  SONET/SDH Circuit Emulation Service Over MPLS    [CEP]\
   0x0009  ATM n-to-one VCC cell transport                  [ATM]\
   0x000A  ATM n-to-one VPC cell transport                  [ATM]\
   0x000B  IP Layer2 Transport                              [RFC3032]\
   0x000C  ATM one-to-one VCC Cell Mode                     [ATM]\
   0x000D  ATM one-to-one VPC Cell Mode                     [ATM]\
   0x000E  ATM AAL5 PDU VCC transport                       [ATM]\
   0x000F  Frame-Relay Port mode                            [FRAME]\
   0x0010  SONET/SDH Circuit Emulation over Packet          [CEP]\
   0x0011  Structure-agnostic E1 over Packet                [SAToP]\
   0x0012  Structure-agnostic T1 (DS1) over Packet          [SAToP]\
   0x0013  Structure-agnostic E3 over Packet                [SAToP]\
   0x0014  Structure-agnostic T3 (DS3) over Packet          [SAToP]\
   0x0015  CESoPSN basic mode                               [CESoPSN]\
   0x0016  TDMoIP AAL1 Mode                                 [TDMoIP]\
   0x0017  CESoPSN TDM with CAS                             [CESoPSN]\
   0x0018  TDMoIP AAL2 Mode                                 [TDMoIP]\
   0x0019  Frame Relay DLCI                                 [FRAME]\
\
\
\
\
\
\
\
Martini                  Best Current Practice                  [Page 3]\
\
RFC 4446               IANA Allocations for PWE3              April 2006\
\
\
3.3.  Interface Parameters Sub-TLV Type\
\
   IANA has to set up the registry of "Pseudowire Interface Parameter\
   Sub-TLV types".  This type has 8-bit values.  Sub-TLV types 1 through\
   12 are specified in this document.  Sub-TLV types 13 through 64 are\
   to be assigned by IANA, using the "Expert Review" policy defined in\
   [RFC2434].  Sub-TLV types 65 through 127 and 255 are to be allocated\
   using the IETF consensus policy defined in [RFC2434].  Sub-TLV types\
   values 128 through 254 are reserved for vendor-proprietary extensions\
   and are to be assigned by IANA, using the "First Come First Served"\
   policy defined in [RFC2434].\
\
   Any assignments requested from this registry require a description of\
   up to 54 characters.\
\
   For each allocation, a length field MUST also be specified in one of\
   the following formats:\
\
      -  Text as follows:"up to X", where X is a decimal integer.\
      - Up to 3 different decimal integers.\
\
   The text "up to X" means up to and including X.\
\
   Additionally, for the vendor-proprietary extensions range, a citation\
   of a person or company name is also required.  A document reference\
   should also be provided.\
\
   Initial Pseudowire Interface Parameter Sub-TLV type allocations are\
   specified below:\
\
Parameter  Length       Description                       Reference\
 ID\
========================================================================\
 0x01      4       Interface MTU in octets               [CRTL]\
 0x02      4       Maximum Number of concatenated ATM cells [ATM]\
 0x03   up to 82   Optional Interface Description string [CRTL][RFC2277]\
 0x04      4       CEP/TDM Payload Bytes                 [CEP][TDMoIP]\
 0x05      4       CEP options                           [CEP]\
 0x06      4       Requested VLAN ID                     [ETH]\
 0x07      6       CEP/TDM bit-rate                      [CEP][TDMoIP]\
 0x08      4       Frame-Relay DLCI Length               [FRAME]\
 0x09      4       Fragmentation indicator               [FRAG]\
 0x0A      4       FCS retention indicator               [FCS]\
 0x0B    4/8/12    TDM options                           [TDMoIP]\
 0x0C      4       VCCV parameter                        [VCCV]\
\
   Note that the Length field is defined as the length of the Sub-TLV,\
   including the Sub-TLV type and length field itself.\
\
\
\
Martini                  Best Current Practice                  [Page 4]\
\
RFC 4446               IANA Allocations for PWE3              April 2006\
\
\
3.4.  Attachment Identifiers\
\
3.4.1.  Attachment Individual Identifier Type\
\
   IANA has to set up the registry of "Attachment Individual Identifier\
   (AII) Type".  This type has 8-bit values.  AII Type value 1 is\
   defined in this document.  AII Type values 2 through 64 are to be\
   assigned by IANA, using the "Expert Review" policy defined in\
   [RFC2434].  AII Type values 65 through 127 and 255 are to be\
   allocated using the IETF consensus policy defined in [RFC2434].  AII\
   types values 128 through 254 are reserved for vendor-proprietary\
   extensions and are to be assigned by IANA, using the "First Come\
   First Served" policy defined in [RFC2434].\
\
   Any assignments requested from this registry require a description of\
   up to 54 characters.\
\
   For each allocation, a length field MUST also be specified as a\
   decimal integer.\
\
   Additionally, for the vendor-proprietary extensions range, a citation\
   of a person or company name is also required.  A document reference\
   should also be provided.\
\
   Initial Attachment Individual Identifier (AII) Type allocations are\
   specified below:\
\
   AII Type     Length    Description                          Reference\
   =====================================================================\
   0x01         4         A 32 bit unsigned number local       [SIG]\
                          identifier.\
\
3.4.2.  Attachment Group Identifier (AGI) Type\
\
   IANA has to set up the registry of "Attachment Group Identifier (AGI)\
   Type".  This type has 8-bit values.  AGI Type value 1 is defined in\
   this document.  AGI Type values 2 through 64 are to be assigned by\
   IANA, using the "Expert Review" policy defined in [RFC2434].  AGI\
   Type values 65 through 127 and 255 are to be allocated using the IETF\
   consensus policy defined in [RFC2434].  AGI type values 128 through\
   254 are reserved for vendor-proprietary extensions and are to be\
   assigned by IANA, using the "First Come First Served" policy defined\
   in [RFC2434].\
\
   Any assignments requested from this registry require a description of\
   up to 54 characters.\
\
\
\
\
\
Martini                  Best Current Practice                  [Page 5]\
\
RFC 4446               IANA Allocations for PWE3              April 2006\
\
\
   For each allocation, a length field MUST also be specified as a\
   decimal integer.\
\
   Additionally, for the vendor-proprietary extensions range, a citation\
   of a person or company name is also required.  A document reference\
   should also be provided.\
\
   Initial Attachment Group Identifier (AGI) Type allocations are\
   specified below:\
\
   AGI Type     Length    Description                        Reference\
    ===================================================================\
    0x01         8         AGI encoded as Route Distinguisher [SIG]\
\
3.5.  Pseudowire Status\
\
   IANA has to set up the registry of "Pseudowire Status Codes".  These\
   are bit strings of length 32.  Status bits 0 through 4 are defined in\
   this document.  Status bits 5 through 31 are to be assigned by IANA\
   using the "Expert Review" policy defined in [RFC2434].\
\
   Any requests for allocation from this registry require a description\
   of up to 65 characters.\
\
   Initial Pseudowire Status Code value allocations are as follows:\
\
   Bit Mask     Description\
   ====================================================================\
   0x00000000 - Pseudowire forwarding (clear all failures)       [CRTL]\
   0x00000001 - Pseudowire Not Forwarding                        [CRTL]\
   0x00000002 - Local Attachment Circuit (ingress) Receive Fault [CRTL]\
   0x00000004 - Local Attachment Circuit (egress) Transmit Fault [CRTL]\
   0x00000008 - Local PSN-facing PW (ingress) Receive Fault      [CRTL]\
   0x00000010 - Local PSN-facing PW (egress) Transmit Fault      [CRTL]\
\
   For the definition of the "PW Associated Channel Type" please refer\
   to [RFC4385].\
\
3.6 PW Associated Channel Type\
\
   For the definition of the "PW Associated Channel Type", please refer\
   to [RFC4385].\
\
\
\
\
\
\
\
\
\
Martini                  Best Current Practice                  [Page 6]\
\
RFC 4446               IANA Allocations for PWE3              April 2006\
\
\
4.  Security Considerations\
\
   This document specifies only fixed identifiers, and not the protocols\
   used to carry the encapsulated packets across the network.  Each such\
   protocol may have its own set of security issues, but those issues\
   are not affected by the identifiers specified herein.\
\
5.  References\
\
5.1.  Normative References\
\
   [RFC2434] Narten, T. and H. Alvestrand, "Guidelines for Writing an\
             IANA Considerations Section in RFCs", BCP 26, RFC 2434,\
             October 1998.\
\
   [RFC2277] Alvestrand, H., "IETF Policy on Character Sets and\
             Languages", BCP 18, RFC 2277, January 1998.\
\
   [RFC2119] Bradner, S., "Key words for use in RFCs to Indicate\
             Requirement Levels", BCP 14, RFC 2119, March 1997.\
\
5.2.  Informative References\
\
   [CRTL]    Martini, L., Ed., Rosen, E., El-Aawar, N., Smith, T., and\
             G. Heron, "Pseudowire Setup and Maintenance Using the Label\
             Distribution Protocol (LDP)", RFC 4447, April 2006.\
\
   [VCCV]    Nadeau, T. and R. Aggarwal, "Pseudo Wire Virtual Circuit\
             Connectivity Verification (VCCV)", Work in Progress, August\
             2005.\
\
   [FRAG]    Malis, A. and M. Townsley, "PWE3 Fragmentation and\
             Reassembly", Work in Progress, September 2005.\
\
   [FCS]     Malis, A., Allan, D., and N. Del Regno, "PWE3 Frame Check\
             Sequence Retention", Work in Progress, September 2005.\
\
   [CEP]     Malis, A., Pate, P., Cohen, R., Ed., and D. Zelig,\
             "SONET/SDH Circuit Emulation Service Over Packet (CEP)",\
             Work in Progress.\
\
   [SAToP]   Vainshtein, A. Ed. and Y. Stein, Ed. "Structure-Agnostic\
             TDM over Packet (SAToP)", Work in Progress.\
\
   [FRAME]   Martini, L., Ed. and C. Kawa, "Encapsulation Methods for\
             Transport of Frame Relay Over MPLS Networks", Work in\
             Progress.\
\
\
\
\
Martini                  Best Current Practice                  [Page 7]\
\
RFC 4446               IANA Allocations for PWE3              April 2006\
\
\
   [ATM]     Martini, L., Ed., El-Aawar, N., and M. Bocci, Ed.,\
             "Encapsulation Methods for Transport of ATM Over MPLS\
             Networks", Work in Progress.\
\
   [PPPHDLC] Martini, L., Rosen, E., Heron, G. and A. Malis,\
             "Encapsulation Methods for Transport of PPP/HDLC Frames\
             Over MPLS Networks", Work in Progress.\
\
   [ETH]     Martini, L., Rosen, E., El-Aawar, N., and G. Heron,\
             "Encapsulation Methods for Transport of Ethernet Frames\
             Over MPLS Networks", RFC 4448, April 2006.\
\
   [CESoPSN] Vainshtein, A., Ed., Sasson, I., Metz, E., Frost, T., and\
             P. Pate, "Structure-aware TDM Circuit Emulation Service\
             over Packet Switched Network (CESoPSN)", Work in Progress.\
\
   [TDMoIP]  Stein, Y., Shashoua, R., Insler, R., and M. Anavi, "TDM\
             over IP", Work in Progress, February 2005.\
\
   [RFC3032] Rosen, E., Tappan, D., Fedorkow, G., Rekhter, Y.,\
             Farinacci, D., Li, T., and A. Conta, "MPLS Label Stack\
             Encoding", RFC 3032, January 2001.\
\
   [SIG]     Rosen, E., Luo, W., Davie, B., and V. Radoaca,\
             "Provisioning, Autodiscovery, and Signaling in L2VPNs",\
             Work in Progress, September 2005.\
\
   [RFC4385] Bryant, S., Swallow, G., Martini, L., and D. McPherson,\
             "Pseudowire Emulation Edge-to-Edge (PWE3) Control Word for\
             Use over an MPLS PSN", RFC 4385, February 2006.\
\
Author's Address\
\
   Luca Martini\
   Cisco Systems, Inc.\
   9155 East Nichols Avenue, Suite 400\
   Englewood, CO, 80112\
\
   EMail: lmartini@cisco.com\
\
\
\
\
\
\
\
\
\
\
\
\
Martini                  Best Current Practice                  [Page 8]\
\
RFC 4446               IANA Allocations for PWE3              April 2006\
\
\
Full Copyright Statement\
\
   Copyright (C) The Internet Society (2006).\
\
   This document is subject to the rights, licenses and restrictions\
   contained in BCP 78, and except as set forth therein, the authors\
   retain all their rights.\
\
   This document and the information contained herein are provided on an\
   "AS IS" basis and THE CONTRIBUTOR, THE ORGANIZATION HE/SHE REPRESENTS\
   OR IS SPONSORED BY (IF ANY), THE INTERNET SOCIETY AND THE INTERNET\
   ENGINEERING TASK FORCE DISCLAIM ALL WARRANTIES, EXPRESS OR IMPLIED,\
   INCLUDING BUT NOT LIMITED TO ANY WARRANTY THAT THE USE OF THE\
   INFORMATION HEREIN WILL NOT INFRINGE ANY RIGHTS OR ANY IMPLIED\
   WARRANTIES OF MERCHANTABILITY OR FITNESS FOR A PARTICULAR PURPOSE.\
\
Intellectual Property\
\
   The IETF takes no position regarding the validity or scope of any\
   Intellectual Property Rights or other rights that might be claimed to\
   pertain to the implementation or use of the technology described in\
   this document or the extent to which any license under such rights\
   might or might not be available; nor does it represent that it has\
   made any independent effort to identify any such rights.  Information\
   on the procedures with respect to rights in RFC documents can be\
   found in BCP 78 and BCP 79.\
\
   Copies of IPR disclosures made to the IETF Secretariat and any\
   assurances of licenses to be made available, or the result of an\
   attempt made to obtain a general license or permission for the use of\
   such proprietary rights by implementers or users of this\
   specification can be obtained from the IETF on-line IPR repository at\
   http://www.ietf.org/ipr.\
\
   The IETF invites any interested party to bring to its attention any\
   copyrights, patents or patent applications, or other proprietary\
   rights that may cover technology that may be required to implement\
   this standard.  Please address the information to the IETF at\
   ietf-ipr@ietf.org.\
\
Acknowledgement\
\
   Funding for the RFC Editor function is provided by the IETF\
   Administrative Support Activity (IASA).\
\
\
\
\
\
\
\
Martini                  Best Current Practice                  [Page 9]\
\

doc 9
  field 0
    name titolo
    type string
    value rfc4449.txt
  field 1
    name contenuto
    type string
    value \
\
\
\
\
\
Network Working Group                                         C. Perkins\
Request for Comments: 4449                         Nokia Research Center\
Category: Standards Track                                      June 2006\
\
\
   Securing Mobile IPv6 Route Optimization Using a Static Shared Key\
\
Status of This Memo\
\
   This document specifies an Internet standards track protocol for the\
   Internet community, and requests discussion and suggestions for\
   improvements.  Please refer to the current edition of the "Internet\
   Official Protocol Standards" (STD 1) for the standardization state\
   and status of this protocol.  Distribution of this memo is unlimited.\
\
Copyright Notice\
\
   Copyright (C) The Internet Society (2006).\
\
Abstract\
\
   A mobile node and a correspondent node may preconfigure data useful\
   for precomputing a Binding Management Key that can subsequently be\
   used for authorizing Binding Updates.\
\
Table of Contents\
\
   1. Introduction ....................................................1\
   2. Applicability Statement .........................................2\
   3. Precomputing a Binding Management Key (Kbm) .....................3\
   4. Security Considerations .........................................4\
   5. Acknowledgement .................................................5\
   6. References ......................................................5\
      6.1. Normative References .......................................5\
      6.2. Informative References .....................................6\
\
1.  Introduction\
\
   This specification introduces an alternative, low-latency security\
   mechanism for protecting signaling related to the route optimization\
   in Mobile IPv6.  The default mechanism specified in [1] uses a\
   periodic return routability test to verify both the "right" of the\
   mobile node to use a specific home address, as well as the validity\
   of the claimed care-of address.  That mechanism requires no\
   configuration and no trusted entities beyond the mobile node's home\
   agent.\
\
\
\
\
\
Perkins                     Standards Track                     [Page 1]\
\
RFC 4449           Shared Data for Precomputable Kbm           June 2006\
\
\
   The mechanism specified in this document, however, requires the\
   configuration of a shared secret between mobile node and its\
   correspondent node.  As a result, messages relating to the\
   routability tests can be omitted, leading to significantly smaller\
   latency.  In addition, the right to use a specific home address is\
   ensured in a stronger manner than in [1].  On the other hand, the\
   applicability of this mechanisms is limited due to the need for\
   preconfiguration.  This mechanism is also limited to use only in\
   scenarios where mobile nodes can be trusted not to misbehave, as the\
   validity of the claimed care-of addresses is not verified.\
\
   The keywords "MUST", "MUST NOT", "REQUIRED", "SHALL", "SHALL NOT",\
   "SHOULD", "SHOULD NOT", "RECOMMENDED", "MAY", and "OPTIONAL" in this\
   document are to be interpreted as described in RFC 2119 [2].  Other\
   terminology is used as already defined in [1].\
\
2.  Applicability Statement\
\
   This mechanism is useful in scenarios where the following conditions\
   are all met:\
\
    -  Mobile node and correspondent node are administered within the\
       same domain.\
\
    -  The correspondent node has good reason to trust the actions of\
       the mobile node.  In particular, the correspondent node needs to\
       be certain that the mobile node will not launch flooding attacks\
       against a third party as described in [5].\
\
    -  The configuration effort related to this mechanism is acceptable.\
       Users MUST be able to generate/select a sufficiently good value\
       for Kcn (see [3])\
\
    -  There is a desire to take advantage of higher efficiency or\
       greater assurance with regards to the correctness of the home\
       address offered via this mechanism.\
\
    -  This mechanism is used only for authenticating Binding Update\
       messages (and not, e.g., data), so the total volume of traffic is\
       low (see RFC 4107 [4], and the discussion in section 4).\
\
   This mechanism can also be useful in software development, testing,\
   and diagnostics related to mobility signaling.\
\
   Generally speaking, the required level of trust that the\
   correspondent node needs for enabling a precomputable Kbm with a\
   mobile node is more often found within relatively small, closed\
   groups of users who are personally familiar with each other, or who\
\
\
\
Perkins                     Standards Track                     [Page 2]\
\
RFC 4449           Shared Data for Precomputable Kbm           June 2006\
\
\
   have some external basis for establishing trustworthy interactions.\
   A typical example scenario where this mechanism is applicable is\
   within a corporation, or between specific users.  Application in the\
   general Internet is typically not possible due to the effort that is\
   required to manually configure the correspondent nodes.  Application\
   at a public network operator is typically not possible due to\
   requirements placed on the trustworthiness of mobile nodes.\
\
3.  Precomputing a Binding Management Key (Kbm)\
\
   A mobile node and a correspondent node may preconfigure data useful\
   for creating a Binding Management Key (Kbm), which can then be used\
   for authorizing binding management messages, especially Binding\
   Update and Binding Acknowledgement messages.  This data is as\
   follows:\
\
    -  A shared key (Kcn) used to generate keygen tokens, at least 20\
       octets long\
\
    -  A nonce for use when generating the care-of keygen token\
\
    -  A nonce for use when generating the home keygen token\
\
   The keygen tokens MUST be generated from Kcn and the nonces as\
   specified in Mobile IPv6 [1] return routability.  Likewise, the\
   binding management key Kbm must subsequently be generated from the\
   keygen tokens in the same way as specified in Mobile IPv6 [1].  The\
   preconfigured data is associated to the mobile node's home address.\
   Kcn MUST be generated with sufficient randomness (see RFC 4086 [3]).\
\
   Replay protection for Binding Update messages using Kbm computed from\
   the preconfigured data depends upon the value of the Sequence Number\
   field in the Binding Update.  If the correspondent node does not\
   maintain information about the recently used values of that field,\
   then there may be an opportunity for a malicious node to replay old\
   Binding Update messages and fool the correspondent node into routing\
   toward an old care-of address.  For this reason, a correspondent node\
   that uses a precomputable Kbm also MUST keep track of the most recent\
   value of the Sequence Number field of Binding Update messages using\
   the precomputable Kbm value (for example, by committing it to stable\
   storage).\
\
\
\
\
\
\
\
\
\
\
Perkins                     Standards Track                     [Page 3]\
\
RFC 4449           Shared Data for Precomputable Kbm           June 2006\
\
\
   When a Binding Update is to be authenticated using such a\
   precomputable binding key (Kbm), the Binding Authorization Data\
   suboption MUST be present.  The Nonce Indices option SHOULD NOT be\
   present.  If it is present, the nonce indices supplied SHOULD be\
   ignored and are not included as part of the calculation for the\
   authentication data, which is to be performed exactly as specified in\
   [1].\
\
4.  Security Considerations\
\
   A correspondent node and a mobile node may use a precomputable\
   binding management key (Kbm) to manage the authentication\
   requirements for binding cache management messages.  Such keys must\
   be handled carefully to avoid inadvertent exposure to the threats\
   outlined in [5].  Many requirements listed in this document are\
   intended to ensure the safety of the manual configuration.  In\
   particular, Kcn MUST be generated with sufficient randomness (see RFC\
   4086 [3]), as noted in Section 3.\
\
   Manually configured keys MUST be used in conformance with RFC 4107\
   [4].  Used according to the applicability statement, and with the\
   other security measures mandated in this specification, the keys will\
   satisfy the properties in that document.  In order to ensure\
   protection against dictionary attacks, the configured security\
   information is intended to be used ONLY for authenticating Binding\
   Update messages.\
\
   A mobile node MUST use a different value for Kcn for each node in its\
   Binding Update List, and a correspondent node MUST ensure that every\
   mobile node uses a different value of Kcn.  This ensures that the\
   sender of a Binding Update can always be uniquely determined.  This\
   is necessary, as this authorization method does not provide any\
   guarantee that the given care-of address is legitimate.  For the same\
   reason, this method SHOULD only be applied between nodes that are\
   under the same administration.  The return routability procedure is\
   RECOMMENDED for all general use and MUST be the default, unless the\
   user explicitly overrides this by entering the aforementioned\
   preconfigured data for a particular peer.\
\
   Replay protection for the Binding Authorization Data option\
   authentication mechanism is provided by the Sequence Number field of\
   the Binding Update.  This method of providing replay protection fails\
   when the Binding Update sequence numbers cycle through the 16 bit\
   counter (i.e., not more than 65,536 distinct uses of Kbm), or if the\
   sequence numbers are not protected against reboots.  If the mobile\
   node were to send a fresh Binding Update to its correspondent node\
   every hour, 24 hours a day, every day of the year, this would require\
   changing keys every 7 years.  Even if the mobile node were to do so\
\
\
\
Perkins                     Standards Track                     [Page 4]\
\
RFC 4449           Shared Data for Precomputable Kbm           June 2006\
\
\
   every minute, this would provide protection for over a month.  Given\
   typical mobility patterns, there is little danger of replay problems;\
   nodes for which problems might arise are expected to use methods\
   other than manual configuration for Kcn and the associated nonces.\
   When the Sequence Number field rolls over, the parties SHOULD\
   configure a new value for Kcn, so that new Kbm values will be\
   computed.\
\
   If a correspondent node does NOT keep track of the sequence number\
   for Binding Update messages from a particular mobile node, then the\
   correspondent node could be fooled into accepting an old value for\
   the mobile node's care-of address.  In the unlikely event that this\
   address was reallocated to another IPv6 node in the meantime, that\
   IPv6 node would then be vulnerable to unwanted traffic emanating from\
   the correspondent node.\
\
   Note that where a node has been configured to use the mechanism\
   specified in this document with a particular peer, it SHOULD NOT\
   attempt to use another mechanism, even if the peer requests this or\
   claims not to support the mechanism in this document.  This is\
   necessary in order to prevent bidding down attacks.\
\
   There is no upper bound on the lifetime defined for the precomputable\
   Kbm.  As noted, the key is very likely to be quite secure over the\
   lifetime of the security association and usefulness of applications\
   between a mobile node and correspondent node that fit the terms\
   specified in section 2.\
\
5. Acknowledgement\
\
   Thanks are due to everyone who reviewed the discussion of issue #146.\
   Thanks to Jari Arkko for supplying text for the Introduction.\
\
6. References\
\
6.1.  Normative References\
\
   [1] Johnson, D., Perkins, C., and J. Arkko, "Mobility Support in\
       IPv6", RFC 3775, June 2004.\
\
   [2] Bradner, S., "Key words for use in RFCs to Indicate Requirement\
       Levels", BCP 14, RFC 2119, March 1997.\
\
   [3] Eastlake, D., 3rd, Schiller, J., and S. Crocker, "Randomness\
       Requirements for Security", BCP 106, RFC 4086, June 2005.\
\
   [4] Bellovin, S. and R. Housley, "Guidelines for Cryptographic Key\
       Management", BCP 107, RFC 4107, June 2005.\
\
\
\
Perkins                     Standards Track                     [Page 5]\
\
RFC 4449           Shared Data for Precomputable Kbm           June 2006\
\
\
6.2. Informative References\
\
   [5] Nikander, P., Arkko, J., Aura, T., Montenegro, G., and E.\
       Nordmark, "Mobile IP Version 6 Route Optimization Security Design\
       Background", RFC 4226, December 2005.\
\
Author's Address\
\
   Charles E. Perkins\
   Nokia Research Center\
   313 Fairchild Drive\
   Mountain View, CA 94043\
   USA\
\
   Phone:  +1 650 625-2986\
   Fax:    +1 650 625-2502\
   EMail:  charles.perkins@nokia.com\
\
\
\
\
\
\
\
\
\
\
\
\
\
\
\
\
\
\
\
\
\
\
\
\
\
\
\
\
\
\
\
\
\
\
Perkins                     Standards Track                     [Page 6]\
\
RFC 4449           Shared Data for Precomputable Kbm           June 2006\
\
\
Full Copyright Statement\
\
   Copyright (C) The Internet Society (2006).\
\
   This document is subject to the rights, licenses and restrictions\
   contained in BCP 78, and except as set forth therein, the authors\
   retain all their rights.\
\
   This document and the information contained herein are provided on an\
   "AS IS" basis and THE CONTRIBUTOR, THE ORGANIZATION HE/SHE REPRESENTS\
   OR IS SPONSORED BY (IF ANY), THE INTERNET SOCIETY AND THE INTERNET\
   ENGINEERING TASK FORCE DISCLAIM ALL WARRANTIES, EXPRESS OR IMPLIED,\
   INCLUDING BUT NOT LIMITED TO ANY WARRANTY THAT THE USE OF THE\
   INFORMATION HEREIN WILL NOT INFRINGE ANY RIGHTS OR ANY IMPLIED\
   WARRANTIES OF MERCHANTABILITY OR FITNESS FOR A PARTICULAR PURPOSE.\
\
Intellectual Property\
\
   The IETF takes no position regarding the validity or scope of any\
   Intellectual Property Rights or other rights that might be claimed to\
   pertain to the implementation or use of the technology described in\
   this document or the extent to which any license under such rights\
   might or might not be available; nor does it represent that it has\
   made any independent effort to identify any such rights.  Information\
   on the procedures with respect to rights in RFC documents can be\
   found in BCP 78 and BCP 79.\
\
   Copies of IPR disclosures made to the IETF Secretariat and any\
   assurances of licenses to be made available, or the result of an\
   attempt made to obtain a general license or permission for the use of\
   such proprietary rights by implementers or users of this\
   specification can be obtained from the IETF on-line IPR repository at\
   http://www.ietf.org/ipr.\
\
   The IETF invites any interested party to bring to its attention any\
   copyrights, patents or patent applications, or other proprietary\
   rights that may cover technology that may be required to implement\
   this standard.  Please address the information to the IETF at\
   ietf-ipr@ietf.org.\
\
Acknowledgement\
\
   Funding for the RFC Editor function is provided by the IETF\
   Administrative Support Activity (IASA).\
\
\
\
\
\
\
\
Perkins                     Standards Track                     [Page 7]\
\

doc 10
  field 0
    name titolo
    type string
    value rfc4474.txt
  field 1
    name contenuto
    type string
    value \
\
\
\
\
\
Network Working Group                                        J. Peterson\
Request for Comments: 4474                                       NeuStar\
Category: Standards Track                                    C. Jennings\
                                                           Cisco Systems\
                                                             August 2006\
\
\
       Enhancements for Authenticated Identity Management in the\
                   Session Initiation Protocol (SIP)\
\
Status of This Memo\
\
   This document specifies an Internet standards track protocol for the\
   Internet community, and requests discussion and suggestions for\
   improvements.  Please refer to the current edition of the "Internet\
   Official Protocol Standards" (STD 1) for the standardization state\
   and status of this protocol.  Distribution of this memo is unlimited.\
\
Copyright Notice\
\
   Copyright (C) The Internet Society (2006).\
\
Abstract\
\
   The existing security mechanisms in the Session Initiation Protocol\
   (SIP) are inadequate for cryptographically assuring the identity of\
   the end users that originate SIP requests, especially in an\
   interdomain context.  This document defines a mechanism for securely\
   identifying originators of SIP messages.  It does so by defining two\
   new SIP header fields, Identity, for conveying a signature used for\
   validating the identity, and Identity-Info, for conveying a reference\
   to the certificate of the signer.\
\
\
\
\
\
\
\
\
\
\
\
\
\
\
\
\
\
\
\
Peterson & Jennings         Standards Track                     [Page 1]\
\
RFC 4474                      SIP Identity                   August 2006\
\
\
Table of Contents\
\
   1. Introduction ....................................................3\
   2. Terminology .....................................................3\
   3. Background ......................................................3\
   4. Overview of Operations ..........................................6\
   5. Authentication Service Behavior .................................7\
      5.1. Identity within a Dialog and Retargeting ..................10\
   6. Verifier Behavior ..............................................11\
   7. Considerations for User Agent ..................................12\
   8. Considerations for Proxy Servers ...............................13\
   9. Header Syntax ..................................................13\
   10. Compliance Tests and Examples .................................16\
      10.1. Identity-Info with a Singlepart MIME body ................17\
      10.2. Identity for a Request with No MIME Body or Contact ......20\
   11. Identity and the TEL URI Scheme ...............................22\
   12. Privacy Considerations ........................................23\
   13. Security Considerations .......................................24\
      13.1. Handling of digest-string Elements .......................24\
      13.2. Display-Names and Identity ...............................27\
      13.3. Securing the Connection to the Authentication Service ....28\
      13.4. Domain Names and Subordination ...........................29\
      13.5. Authorization and Transitional Strategies ................30\
   14. IANA Considerations ...........................................31\
      14.1. Header Field Names .......................................31\
      14.2. 428 'Use Identity Header' Response Code ..................32\
      14.3. 436 'Bad Identity-Info' Response Code ....................32\
      14.4. 437 'Unsupported Certificate' Response Code ..............32\
      14.5. 438 'Invalid Identity Header' Response Code ..............33\
      14.6. Identity-Info Parameters .................................33\
      14.7. Identity-Info Algorithm Parameter Values .................33\
   Appendix A. Acknowledgements ......................................34\
   Appendix B. Bit-Exact Archive of Examples of Messages .............34\
      B.1. Encoded Reference Files ...................................35\
   Appendix C. Original Requirements .................................38\
   References ........................................................39\
      Normative References ...........................................39\
      Informative References .........................................39\
\
\
\
\
\
\
\
\
\
\
\
\
\
Peterson & Jennings         Standards Track                     [Page 2]\
\
RFC 4474                      SIP Identity                   August 2006\
\
\
1.  Introduction\
\
   This document provides enhancements to the existing mechanisms for\
   authenticated identity management in the Session Initiation Protocol\
   (SIP, RFC 3261 [1]).  An identity, for the purposes of this document,\
   is defined as a SIP URI, commonly a canonical address-of-record (AoR)\
   employed to reach a user (such as 'sip:alice@atlanta.example.com').\
\
   RFC 3261 stipulates several places within a SIP request where a user\
   can express an identity for themselves, notably the user-populated\
   From header field.  However, the recipient of a SIP request has no\
   way to verify that the From header field has been populated\
   appropriately, in the absence of some sort of cryptographic\
   authentication mechanism.\
\
   RFC 3261 specifies a number of security mechanisms that can be\
   employed by SIP user agents (UAs), including Digest, Transport Layer\
   Security (TLS), and S/MIME (implementations may support other\
   security schemes as well).  However, few SIP user agents today\
   support the end-user certificates necessary to authenticate\
   themselves (via S/MIME, for example), and furthermore Digest\
   authentication is limited by the fact that the originator and\
   destination must share a prearranged secret.  It is desirable for SIP\
   user agents to be able to send requests to destinations with which\
   they have no previous association -- just as in the telephone network\
   today, one can receive a call from someone with whom one has no\
   previous association, and still have a reasonable assurance that the\
   person's displayed Caller-ID is accurate.  A cryptographic approach,\
   like the one described in this document, can probably provide a much\
   stronger and less-spoofable assurance of identity than the telephone\
   network provides today.\
\
2.  Terminology\
\
   In this document, the key words "MUST", "MUST NOT", "REQUIRED",\
   "SHALL", "SHALL NOT", "SHOULD", "SHOULD NOT", "RECOMMENDED", "NOT\
   RECOMMENDED", "MAY", and "OPTIONAL" are to be interpreted as\
   described in RFC 2119 [2] and indicate requirement levels for\
   compliant SIP implementations.\
\
3.  Background\
\
   The usage of many SIP applications and services is governed by\
   authorization policies.  These policies may be automated, or they may\
   be applied manually by humans.  An example of the latter would be an\
   Internet telephone application that displays the Caller-ID of a\
   caller, which a human may review before answering a call.  An example\
   of the former would be a presence service that compares the identity\
\
\
\
Peterson & Jennings         Standards Track                     [Page 3]\
\
RFC 4474                      SIP Identity                   August 2006\
\
\
   of potential subscribers to a whitelist before determining whether it\
   should accept or reject the subscription.  In both of these cases,\
   attackers might attempt to circumvent these authorization policies\
   through impersonation.  Since the primary identifier of the sender of\
   a SIP request, the From header field, can be populated arbitrarily by\
   the controller of a user agent, impersonation is very simple today.\
   The mechanism described in this document aspires to provide a strong\
   identity system for SIP in which authorization policies cannot be\
   circumvented by impersonation.\
\
   All RFC 3261-compliant user agents support Digest authentication,\
   which utilizes a shared secret, as a means for authenticating\
   themselves to a SIP registrar.  Registration allows a user agent to\
   express that it is an appropriate entity to which requests should be\
   sent for a particular SIP AoR URI (e.g.,\
   'sip:alice@atlanta.example.com').\
\
   By the definition of identity used in this document, registration is\
   a proof of the identity of the user to a registrar.  However, the\
   credentials with which a user agent proves its identity to a\
   registrar cannot be validated by just any user agent or proxy server\
   -- these credentials are only shared between the user agent and their\
   domain administrator.  So this shared secret does not immediately\
   help a user to authenticate to a wide range of recipients.\
   Recipients require a means of determining whether or not the 'return\
   address' identity of a non-REGISTER request (i.e., the From header\
   field value) has legitimately been asserted.\
\
   The AoR URI used for registration is also the URI with which a UA\
   commonly populates the From header field of requests in order to\
   provide a 'return address' identity to recipients.  From an\
   authorization perspective, if you can prove you are eligible to\
   register in a domain under a particular AoR, you can prove you can\
   legitimately receive requests for that AoR, and accordingly, when you\
   place that AoR in the From header field of a SIP request other than a\
   registration (like an INVITE), you are providing a 'return address'\
   where you can legitimately be reached.  In other words, if you are\
   authorized to receive requests for that 'return address', logically,\
   it follows that you are also authorized to assert that 'return\
   address' in your From header field.  This is of course only one\
   manner in which a domain might determine how a particular user is\
   authorized to populate the From header field; as an aside, for other\
   sorts of URIs in the From (like anonymous URIs), other authorization\
   policies would apply.\
\
   Ideally, then, SIP user agents should have some way of proving to\
   recipients of SIP requests that their local domain has authenticated\
   them and authorized the population of the From header field.  This\
\
\
\
Peterson & Jennings         Standards Track                     [Page 4]\
\
RFC 4474                      SIP Identity                   August 2006\
\
\
   document proposes a mediated authentication architecture for SIP in\
   which requests are sent to a server in the user's local domain, which\
   authenticates such requests (using the same practices by which the\
   domain would authenticate REGISTER requests).  Once a message has\
   been authenticated, the local domain then needs some way to\
   communicate to other SIP entities that the sending user has been\
   authenticated and its use of the From header field has been\
   authorized.  This document addresses how that imprimatur of\
   authentication can be shared.\
\
   RFC 3261 already describes an architecture very similar to this in\
   Section 26.3.2.2, in which a user agent authenticates itself to a\
   local proxy server, which in turn authenticates itself to a remote\
   proxy server via mutual TLS, creating a two-link chain of transitive\
   authentication between the originator and the remote domain.  While\
   this works well in some architectures, there are a few respects in\
   which this is impractical.  For one, transitive trust is inherently\
   weaker than an assertion that can be validated end-to-end.  It is\
   possible for SIP requests to cross multiple intermediaries in\
   separate administrative domains, in which case transitive trust\
   becomes even less compelling.\
\
   One solution to this problem is to use 'trusted' SIP intermediaries\
   that assert an identity for users in the form of a privileged SIP\
   header.  A mechanism for doing so (with the P-Asserted-Identity\
   header) is given in [12].  However, this solution allows only hop-\
   by-hop trust between intermediaries, not end-to-end cryptographic\
   authentication, and it assumes a managed network of nodes with strict\
   mutual trust relationships, an assumption that is incompatible with\
   widespread Internet deployment.\
\
   Accordingly, this document specifies a means of sharing a\
   cryptographic assurance of end-user SIP identity in an interdomain or\
   intradomain context that is based on the concept of an\
   'authentication service' and a new SIP header, the Identity header.\
   Note that the scope of this document is limited to providing this\
   identity assurance for SIP requests; solving this problem for SIP\
   responses is more complicated and is a subject for future work.\
\
   This specification allows either a user agent or a proxy server to\
   provide identity services and to verify identities.  To maximize\
   end-to-end security, it is obviously preferable for end-users to\
   acquire their own certificates and corresponding private keys; if\
   they do, they can act as an authentication service.  However, end-\
   user certificates may be neither practical nor affordable, given the\
   difficulties of establishing a Public Key Infrastructure (PKI) that\
   extends to end-users, and moreover, given the potentially large\
   number of SIP user agents (phones, PCs, laptops, PDAs, gaming\
\
\
\
Peterson & Jennings         Standards Track                     [Page 5]\
\
RFC 4474                      SIP Identity                   August 2006\
\
\
   devices) that may be employed by a single user.  In such\
   environments, synchronizing keying material across multiple devices\
   may be very complex and requires quite a good deal of additional\
   endpoint behavior.  Managing several certificates for the various\
   devices is also quite problematic and unpopular with users.\
   Accordingly, in the initial use of this mechanism, it is likely that\
   intermediaries will instantiate the authentication service role.\
\
4.  Overview of Operations\
\
   This section provides an informative (non-normative) high-level\
   overview of the mechanisms described in this document.\
\
   Imagine the case where Alice, who has the home proxy of example.com\
   and the address-of-record sip:alice@example.com, wants to communicate\
   with sip:bob@example.org.\
\
   Alice generates an INVITE and places her identity in the From header\
   field of the request.  She then sends an INVITE over TLS to an\
   authentication service proxy for her domain.\
\
   The authentication service authenticates Alice (possibly by sending a\
   Digest authentication challenge) and validates that she is authorized\
   to assert the identity that is populated in the From header field.\
   This value may be Alice's AoR, or it may be some other value that the\
   policy of the proxy server permits her to use.  It then computes a\
   hash over some particular headers, including the From header field\
   and the bodies in the message.  This hash is signed with the\
   certificate for the domain (example.com, in Alice's case) and\
   inserted in a new header field in the SIP message, the 'Identity'\
   header.\
\
   The proxy, as the holder of the private key of its domain, is\
   asserting that the originator of this request has been authenticated\
   and that she is authorized to claim the identity (the SIP address-\
   of-record) that appears in the From header field.  The proxy also\
   inserts a companion header field, Identity-Info, that tells Bob how\
   to acquire its certificate, if he doesn't already have it.\
\
   When Bob's domain receives the request, it verifies the signature\
   provided in the Identity header, and thus can validate that the\
   domain indicated by the host portion of the AoR in the From header\
   field authenticated the user, and permitted the user to assert that\
   From header field value.  This same validation operation may be\
   performed by Bob's user agent server (UAS).\
\
\
\
\
\
\
Peterson & Jennings         Standards Track                     [Page 6]\
\
RFC 4474                      SIP Identity                   August 2006\
\
\
5.  Authentication Service Behavior\
\
   This document defines a new role for SIP entities called an\
   authentication service.  The authentication service role can be\
   instantiated by a proxy server or a user agent.  Any entity that\
   instantiates the authentication service role MUST possess the private\
   key of a domain certificate.  Intermediaries that instantiate this\
   role MUST be capable of authenticating one or more SIP users that can\
   register in that domain.  Commonly, this role will be instantiated by\
   a proxy server, since these entities are more likely to have a static\
   hostname, hold a corresponding certificate, and have access to SIP\
   registrar capabilities that allow them to authenticate users in their\
   domain.  It is also possible that the authentication service role\
   might be instantiated by an entity that acts as a redirect server,\
   but that is left as a topic for future work.\
\
   SIP entities that act as an authentication service MUST add a Date\
   header field to SIP requests if one is not already present (see\
   Section 9 for information on how the Date header field assists\
   verifiers).  Similarly, authentication services MUST add a Content-\
   Length header field to SIP requests if one is not already present;\
   this can help verifiers to double-check that they are hashing exactly\
   as many bytes of message-body as the authentication service when they\
   verify the message.\
\
   Entities instantiating the authentication service role perform the\
   following steps, in order, to generate an Identity header for a SIP\
   request:\
\
   Step 1:\
\
   The authentication service MUST extract the identity of the sender\
   from the request.  The authentication service takes this value from\
   the From header field; this AoR will be referred to here as the\
   'identity field'.  If the identity field contains a SIP or SIP Secure\
   (SIPS) URI, the authentication service MUST extract the hostname\
   portion of the identity field and compare it to the domain(s) for\
   which it is responsible (following the procedures in RFC 3261,\
   Section 16.4, used by a proxy server to determine the domain(s) for\
   which it is responsible).  If the identity field uses the TEL URI\
   scheme, the policy of the authentication service determines whether\
   or not it is responsible for this identity; see Section 11 for more\
   information.  If the authentication service is not responsible for\
   the identity in question, it SHOULD process and forward the request\
   normally, but it MUST NOT add an Identity header; see below for more\
   information on authentication service handling of an existing\
   Identity header.\
\
\
\
\
Peterson & Jennings         Standards Track                     [Page 7]\
\
RFC 4474                      SIP Identity                   August 2006\
\
\
   Step 2:\
\
   The authentication service MUST determine whether or not the sender\
   of the request is authorized to claim the identity given in the\
   identity field.  In order to do so, the authentication service MUST\
   authenticate the sender of the message.  Some possible ways in which\
   this authentication might be performed include:\
\
         If the authentication service is instantiated by a SIP\
         intermediary (proxy server), it may challenge the request with\
         a 407 response code using the Digest authentication scheme (or\
         viewing a Proxy-Authentication header sent in the request,\
         which was sent in anticipation of a challenge using cached\
         credentials, as described in RFC 3261, Section 22.3).  Note\
         that if that proxy server is maintaining a TLS connection with\
         the client over which the client had previously authenticated\
         itself using Digest authentication, the identity value obtained\
         from that previous authentication step can be reused without an\
         additional Digest challenge.\
\
         If the authentication service is instantiated by a SIP user\
         agent, a user agent can be said to authenticate its user on the\
         grounds that the user can provision the user agent with the\
         private key of the domain, or preferably by providing a\
         password that unlocks said private key.\
\
   Authorization of the use of a particular username in the From header\
   field is a matter of local policy for the authentication service, one\
   that depends greatly on the manner in which authentication is\
   performed.  For example, one policy might be as follows: the username\
   given in the 'username' parameter of the Proxy-Authorization header\
   MUST correspond exactly to the username in the From header field of\
   the SIP message.  However, there are many cases in which this is too\
   limiting or inappropriate; a realm might use 'username' parameters in\
   Proxy-Authorization that do not correspond to the user-portion of SIP\
   From headers, or a user might manage multiple accounts in the same\
   administrative domain.  In this latter case, a domain might maintain\
   a mapping between the values in the 'username' parameter of Proxy-\
   Authorization and a set of one or more SIP URIs that might\
   legitimately be asserted for that 'username'.  For example, the\
   username can correspond to the 'private identity' as defined in Third\
   Generation Partnership Project (3GPP), in which case the From header\
   field can contain any one of the public identities associated with\
   this private identity.  In this instance, another policy might be as\
   follows: the URI in the From header field MUST correspond exactly to\
   one of the mapped URIs associated with the 'username' given in the\
   Proxy-Authorization header.  Various exceptions to such policies\
   might arise for cases like anonymity; if the AoR asserted in the From\
\
\
\
Peterson & Jennings         Standards Track                     [Page 8]\
\
RFC 4474                      SIP Identity                   August 2006\
\
\
   header field uses a form like 'sip:anonymous@example.com', then the\
   'example.com' proxy should authenticate that the user is a valid user\
   in the domain and insert the signature over the From header field as\
   usual.\
\
   Note that this check is performed on the addr-spec in the From header\
   field (e.g., the URI of the sender, like\
   'sip:alice@atlanta.example.com'); it does not convert the display-\
   name portion of the From header field (e.g., 'Alice Atlanta').\
   Authentication services MAY check and validate the display-name as\
   well, and compare it to a list of acceptable display-names that may\
   be used by the sender; if the display-name does not meet policy\
   constraints, the authentication service MUST return a 403 response\
   code.  The reason phrase should indicate the nature of the problem;\
   for example, "Inappropriate Display Name".  However, the display-name\
   is not always present, and in many environments the requisite\
   operational procedures for display-name validation may not exist.\
   For more information, see Section 13.2.\
\
   Step 3:\
\
   The authentication service SHOULD ensure that any preexisting Date\
   header in the request is accurate.  Local policy can dictate\
   precisely how accurate the Date must be; a RECOMMENDED maximum\
   discrepancy of ten minutes will ensure that the request is unlikely\
   to upset any verifiers.  If the Date header contains a time different\
   by more than ten minutes from the current time noted by the\
   authentication service, the authentication service SHOULD reject the\
   request.  This behavior is not mandatory because a user agent client\
   (UAC) could only exploit the Date header in order to cause a request\
   to fail verification; the Identity header is not intended to provide\
   a source of non-repudiation or a perfect record of when messages are\
   processed.  Finally, the authentication service MUST verify that the\
   Date header falls within the validity period of its certificate.  For\
   more information on the security properties associated with the Date\
   header field value, see Section 9.\
\
   Step 4:\
\
   The authentication service MUST form the identity signature and add\
   an Identity header to the request containing this signature.  After\
   the Identity header has been added to the request, the authentication\
   service MUST also add an Identity-Info header.  The Identity-Info\
   header contains a URI from which its certificate can be acquired.\
   Details on the generation of both of these headers are provided in\
   Section 9.\
\
\
\
\
\
Peterson & Jennings         Standards Track                     [Page 9]\
\
RFC 4474                      SIP Identity                   August 2006\
\
\
   Finally, the authentication service MUST forward the message\
   normally.\
\
5.1.  Identity within a Dialog and Retargeting\
\
   Retargeting is broadly defined as the alteration of the Request-URI\
   by intermediaries.  More specifically, retargeting supplants the\
   original target URI with one that corresponds to a different user, a\
   user that is not authorized to register under the original target\
   URI.  By this definition, retargeting does not include translation of\
   the Request-URI to a contact address of an endpoint that has\
   registered under the original target URI, for example.\
\
   When a dialog-forming request is retargeted, this can cause a few\
   wrinkles for the Identity mechanism when it is applied to requests\
   sent in the backwards direction within a dialog.  This section\
   provides some non-normative considerations related to this case.\
\
   When a request is retargeted, it may reach a SIP endpoint whose user\
   is not identified by the URI designated in the To header field value.\
   The value in the To header field of a dialog-forming request is used\
   as the From header field of requests sent in the backwards direction\
   during the dialog, and is accordingly the header that would be signed\
   by an authentication service for requests sent in the backwards\
   direction.  In retargeting cases, if the URI in the From header does\
   not identify the sender of the request in the backwards direction,\
   then clearly it would be inappropriate to provide an Identity\
   signature over that From header.  As specified above, if the\
   authentication service is not responsible for the domain in the From\
   header field of the request, it MUST NOT add an Identity header to\
   the request, and it should process/forward the request normally.\
\
   Any means of anticipating retargeting, and so on, is outside the\
   scope of this document, and likely to have equal applicability to\
   response identity as it does to requests in the backwards direction\
   within a dialog.  Consequently, no special guidance is given for\
   implementers here regarding the 'connected party' problem;\
   authentication service behavior is unchanged if retargeting has\
   occurred for a dialog-forming request.  Ultimately, the\
   authentication service provides an Identity header for requests in\
   the backwards dialog when the user is authorized to assert the\
   identity given in the From header field, and if they are not, an\
   Identity header is not provided.\
\
   For further information on the problems of response identity and the\
   potential solution spaces, see [15].\
\
\
\
\
\
Peterson & Jennings         Standards Track                    [Page 10]\
\
RFC 4474                      SIP Identity                   August 2006\
\
\
6.  Verifier Behavior\
\
   This document introduces a new logical role for SIP entities called a\
   server.  When a verifier receives a SIP message containing an\
   Identity header, it may inspect the signature to verify the identity\
   of the sender of the message.  Typically, the results of a\
   verification are provided as input to an authorization process that\
   is outside the scope of this document.  If an Identity header is not\
   present in a request, and one is required by local policy (for\
   example, based on a per-sending-domain policy, or a per-sending-user\
   policy), then a 428 'Use Identity Header' response MUST be sent.\
\
   In order to verify the identity of the sender of a message, an entity\
   acting as a verifier MUST perform the following steps, in the order\
   here specified.\
\
   Step 1:\
\
   The verifier MUST acquire the certificate for the signing domain.\
   Implementations supporting this specification SHOULD have some means\
   of retaining domain certificates (in accordance with normal practices\
   for certificate lifetimes and revocation) in order to prevent\
   themselves from needlessly downloading the same certificate every\
   time a request from the same domain is received.  Certificates cached\
   in this manner should be indexed by the URI given in the Identity-\
   Info header field value.\
\
   Provided that the domain certificate used to sign this message is not\
   previously known to the verifier, SIP entities SHOULD discover this\
   certificate by dereferencing the Identity-Info header, unless they\
   have some more efficient implementation-specific way of acquiring\
   certificates for that domain.  If the URI scheme in the Identity-Info\
   header cannot be dereferenced, then a 436 'Bad Identity-Info'\
   response MUST be returned.  The verifier processes this certificate\
   in the usual ways, including checking that it has not expired, that\
   the chain is valid back to a trusted certification authority (CA),\
   and that it does not appear on revocation lists.  Once the\
   certificate is acquired, it MUST be validated following the\
   procedures in RFC 3280 [9].  If the certificate cannot be validated\
   (it is self-signed and untrusted, or signed by an untrusted or\
   unknown certificate authority, expired, or revoked), the verifier\
   MUST send a 437 'Unsupported Certificate' response.\
\
   Step 2:\
\
   The verifier MUST follow the process described in Section 13.4 to\
   determine if the signer is authoritative for the URI in the From\
   header field.\
\
\
\
Peterson & Jennings         Standards Track                    [Page 11]\
\
RFC 4474                      SIP Identity                   August 2006\
\
\
   Step 3:\
\
   The verifier MUST verify the signature in the Identity header field,\
   following the procedures for generating the hashed digest-string\
   described in Section 9.  If a verifier determines that the signature\
   on the message does not correspond to the reconstructed digest-\
   string, then a 438 'Invalid Identity Header' response MUST be\
   returned.\
\
   Step 4:\
\
   The verifier MUST validate the Date, Contact, and Call-ID headers in\
   the manner described in Section 13.1; recipients that wish to verify\
   Identity signatures MUST support all of the operations described\
   there.  It must furthermore ensure that the value of the Date header\
   falls within the validity period of the certificate whose\
   corresponding private key was used to sign the Identity header.\
\
7.  Considerations for User Agent\
\
   This mechanism can be applied opportunistically to existing SIP\
   deployments; accordingly, it requires no change to SIP user agent\
   behavior in order for it to be effective.  However, because this\
   mechanism does not provide integrity protection between the UAC and\
   the authentication service, a UAC SHOULD implement some means of\
   providing this integrity.  TLS would be one such mechanism, which is\
   attractive because it MUST be supported by SIP proxy servers, but is\
   potentially problematic because it is a hop-by-hop mechanism.  See\
   Section 13.3 for more information about securing the channel between\
   the UAC and the authentication service.\
\
   When a UAC sends a request, it MUST accurately populate the From\
   header field with a value corresponding to an identity that it\
   believes it is authorized to claim.  In a request, it MUST set the\
   URI portion of its From header to match a SIP, SIPS, or TEL URI AoR\
   that it is authorized to use in the domain (including anonymous URIs,\
   as described in RFC 3323 [3]).  In general, UACs SHOULD NOT use the\
   TEL URI form in the From header field (see Section 11).\
\
   Note that this document defines a number of new 4xx response codes.\
   If user agents support these response codes, they will be able to\
   respond intelligently to Identity-based error conditions.\
\
   The UAC MUST also be capable of sending requests, including mid-call\
   requests, through an 'outbound' proxy (the authentication service).\
   The best way to accomplish this is using pre-loaded Route headers and\
   loose routing.  For a given domain, if an entity that can instantiate\
   the authentication service role is not in the path of dialog-forming\
\
\
\
Peterson & Jennings         Standards Track                    [Page 12]\
\
RFC 4474                      SIP Identity                   August 2006\
\
\
   requests, identity for mid-dialog requests in the backwards direction\
   cannot be provided.\
\
   As a recipient of a request, a user agent that can verify signed\
   identities should also support an appropriate user interface to\
   render the validity of identity to a user.  User agent\
   implementations SHOULD differentiate signed From header field values\
   from unsigned From header field values when rendering to an end-user\
   the identity of the sender of a request.\
\
8.  Considerations for Proxy Servers\
\
   Domain policy may require proxy servers to inspect and verify the\
   identity provided in SIP requests.  A proxy server may wish to\
   ascertain the identity of the sender of the message to provide spam\
   prevention or call control services.  Even if a proxy server does not\
   act as an authentication service, it MAY validate the Identity header\
   before it makes a forwarding decision for a request.  Proxy servers\
   MUST NOT remove or modify an existing Identity or Identity-Info\
   header in a request.\
\
9.  Header Syntax\
\
   This document specifies two new SIP headers: Identity and Identity-\
   Info.  Each of these headers can appear only once in a SIP message.\
   The grammar for these two headers is (following the ABNF [6] in RFC\
   3261 [1]):\
\
   Identity = "Identity" HCOLON signed-identity-digest\
   signed-identity-digest = LDQUOT 32LHEX RDQUOT\
\
   Identity-Info = "Identity-Info" HCOLON ident-info\
                    *( SEMI ident-info-params )\
   ident-info = LAQUOT absoluteURI RAQUOT\
   ident-info-params = ident-info-alg / ident-info-extension\
   ident-info-alg = "alg" EQUAL token\
   ident-info-extension = generic-param\
\
   The signed-identity-digest is a signed hash of a canonical string\
   generated from certain components of a SIP request.  To create the\
   contents of the signed-identity-digest, the following elements of a\
   SIP message MUST be placed in a bit-exact string in the order\
   specified here, separated by a vertical line, "|" or %x7C, character:\
\
   o  The AoR of the UA sending the message, or addr-spec of the From\
      header field (referred to occasionally here as the 'identity\
      field').\
\
\
\
\
Peterson & Jennings         Standards Track                    [Page 13]\
\
RFC 4474                      SIP Identity                   August 2006\
\
\
   o  The addr-spec component of the To header field, which is the AoR\
      to which the request is being sent.\
   o  The callid from Call-Id header field.\
   o  The digit (1*DIGIT) and method (method) portions from CSeq header\
      field, separated by a single space (ABNF SP, or %x20).  Note that\
      the CSeq header field allows linear whitespace (LWS) rather than\
      SP to separate the digit and method portions, and thus the CSeq\
      header field may need to be transformed in order to be\
      canonicalized.  The authentication service MUST strip leading\
      zeros from the 'digit' portion of the Cseq before generating the\
      digest-string.\
   o  The Date header field, with exactly one space each for each SP and\
      the weekday and month items case set as shown in BNF in RFC 3261.\
      RFC 3261 specifies that the BNF for weekday and month is a choice\
      amongst a set of tokens.  The RFC 2234 rules for the BNF specify\
      that tokens are case sensitive.  However, when used to construct\
      the canonical string defined here, the first letter of each week\
      and month MUST be capitalized, and the remaining two letters must\
      be lowercase.  This matches the capitalization provided in the\
      definition of each token.  All requests that use the Identity\
      mechanism MUST contain a Date header.\
   o  The addr-spec component of the Contact header field value.  If the\
      request does not contain a Contact header, this field MUST be\
      empty (i.e., there will be no whitespace between the fourth and\
      fifth "|" characters in the canonical string).\
   o  The body content of the message with the bits exactly as they are\
      in the Message (in the ABNF for SIP, the message-body).  This\
      includes all components of multipart message bodies.  Note that\
      the message-body does NOT include the CRLF separating the SIP\
      headers from the message-body, but does include everything that\
      follows that CRLF.  If the message has no body, then message-body\
      will be empty, and the final "|" will not be followed by any\
      additional characters.\
\
   For more information on the security properties of these headers, and\
   why their inclusion mitigates replay attacks, see Section 13 and [5].\
   The precise formulation of this digest-string is, therefore\
   (following the ABNF [6] in RFC 3261 [1]):\
\
   digest-string = addr-spec "|" addr-spec "|" callid "|"\
                   1*DIGIT SP Method "|" SIP-date "|" [ addr-spec ] "|"\
                   message-body\
\
   Note again that the first addr-spec MUST be taken from the From\
   header field value, the second addr-spec MUST be taken from the To\
   header field value, and the third addr-spec MUST be taken from the\
   Contact header field value, provided the Contact header is present in\
   the request.\
\
\
\
Peterson & Jennings         Standards Track                    [Page 14]\
\
RFC 4474                      SIP Identity                   August 2006\
\
\
   After the digest-string is formed, it MUST be hashed and signed with\
   the certificate for the domain.  The hashing and signing algorithm is\
   specified by the 'alg' parameter of the Identity-Info header (see\
   below for more information on Identity-Info header parameters).  This\
   document defines only one value for the 'alg' parameter: 'rsa-sha1';\
   further values MUST be defined in a Standards Track RFC, see Section\
   14.7 for more information.  All implementations of this specification\
   MUST support 'rsa-sha1'.  When the 'rsa-sha1' algorithm is specified\
   in the 'alg' parameter of Identity-Info, the hash and signature MUST\
   be generated as follows: compute the results of signing this string\
   with sha1WithRSAEncryption as described in RFC 3370 [7] and base64\
   encode the results as specified in RFC 3548 [8].  A 1024-bit or\
   longer RSA key MUST be used.  The result is placed in the Identity\
   header field.  For detailed examples of the usage of this algorithm,\
   see Section 10.\
\
   The 'absoluteURI' portion of the Identity-Info header MUST contain a\
   URI which dereferences to a resource containing the certificate of\
   the authentication service.  All implementations of this\
   specification MUST support the use of HTTP and HTTPS URIs in the\
   Identity-Info header.  Such HTTP and HTTPS URIs MUST follow the\
   conventions of RFC 2585 [10], and for those URIs the indicated\
   resource MUST be of the form 'application/pkix-cert' described in\
   that specification.  Note that this introduces key lifecycle\
   management concerns; were a domain to change the key available at the\
   Identity-Info URI before a verifier evaluates a request signed by an\
   authentication service, this would cause obvious verifier failures.\
   When a rollover occurs, authentication services SHOULD thus provide\
   new Identity-Info URIs for each new certificate, and SHOULD continue\
   to make older key acquisition URIs available for a duration longer\
   than the plausible lifetime of a SIP message (an hour would most\
   likely suffice).\
\
   The Identity-Info header field MUST contain an 'alg' parameter.  No\
   other parameters are defined for the Identity-Info header in this\
   document.  Future Standards Track RFCs may define additional\
   Identity-Info header parameters.\
\
\
\
\
\
\
\
\
\
\
\
\
\
\
Peterson & Jennings         Standards Track                    [Page 15]\
\
RFC 4474                      SIP Identity                   August 2006\
\
\
   This document adds the following entries to Table 2 of RFC 3261 [1]:\
\
      Header field         where   proxy   ACK  BYE  CAN  INV  OPT  REG\
      ------------         -----   -----   ---  ---  ---  ---  ---  ---\
      Identity               R       a      o    o    -    o    o    o\
\
                                           SUB  NOT  REF  INF  UPD  PRA\
                                           ---  ---  ---  ---  ---  ---\
                                            o    o    o    o    o    o\
\
\
      Header field         where   proxy   ACK  BYE  CAN  INV  OPT  REG\
      ------------         -----   -----   ---  ---  ---  ---  ---  ---\
      Identity-Info          R       a      o    o    -    o    o    o\
\
                                           SUB  NOT  REF  INF  UPD  PRA\
                                           ---  ---  ---  ---  ---  ---\
                                            o    o    o    o    o    o\
\
   Note, in the table above, that this mechanism does not protect the\
   CANCEL method.  The CANCEL method cannot be challenged, because it is\
   hop-by-hop, and accordingly authentication service behavior for\
   CANCEL would be significantly limited.  Note as well that the\
   REGISTER method uses Contact header fields in very unusual ways that\
   complicate its applicability to this mechanism, and the use of\
   Identity with REGISTER is consequently a subject for future study,\
   although it is left as optional here for forward-compatibility\
   reasons.  The Identity and Identity-Info header MUST NOT appear in\
   CANCEL.\
\
10.  Compliance Tests and Examples\
\
   The examples in this section illustrate the use of the Identity\
   header in the context of a SIP transaction.  Implementers are advised\
   to verify their compliance with the specification against the\
   following criteria:\
\
   o  Implementations of the authentication service role MUST generate\
      identical base64 identity strings to the ones shown in the\
      Identity headers in these examples when presented with the source\
      message and utilizing the appropriate supplied private key for the\
      domain in question.\
   o  Implementations of the verifier role MUST correctly validate the\
      given messages containing the Identity header when utilizing the\
      supplied certificates (with the caveat about self-signed\
      certificates below).\
\
\
\
\
\
Peterson & Jennings         Standards Track                    [Page 16]\
\
RFC 4474                      SIP Identity                   August 2006\
\
\
   Note that the following examples use self-signed certificates, rather\
   than certificates issued by a recognized certificate authority.  The\
   use of self-signed certificates for this mechanism is NOT\
   RECOMMENDED, and it appears here only for illustrative purposes.\
   Therefore, in compliance testing, implementations of verifiers SHOULD\
   generate appropriate warnings about the use of self-signed\
   certificates.  Also, the example certificates in this section have\
   placed their domain name subject in the subjectAltName field; in\
   practice, certificate authorities may place domain names in other\
   locations in the certificate (see Section 13.4 for more information).\
\
   Note that all examples in this section use the 'rsa-sha1' algorithm.\
\
   Bit-exact reference files for these messages and their various\
   transformations are supplied in Appendix B.\
\
10.1.  Identity-Info with a Singlepart MIME body\
\
   Consider the following private key and certificate pair assigned to\
   'atlanta.example.com' (rendered in OpenSSL format).\
\
   -----BEGIN RSA PRIVATE KEY-----\
   MIICXQIBAAKBgQDPPMBtHVoPkXV+Z6jq1LsgfTELVWpy2BVUffJMPH06LL0cJSQO\
   aIeVzIojzWtpauB7IylZKlAjB5f429tRuoUiedCwMLKblWAqZt6eHWpCNZJ7lONc\
   IEwnmh2nAccKk83Lp/VH3tgAS/43DQoX2sndnYh+g8522Pzwg7EGWspzzwIDAQAB\
   AoGBAK0W3tnEFD7AjVQAnJNXDtx59Aa1Vu2JEXe6oi+OrkFysJjbZJwsLmKtrgtt\
   PXOU8t2mZpi0wK4hX4tZhntiwGKkUPC3h9Bjp+GerifP341RMyMO+6fPgjqOzUDw\
   +rPjjMpwD7AkcEcqDgbTrZnWv/QnCSaaF3xkUGfFkLx5OKcRAkEA7UxnsE8XaT30\
   tP/UUc51gNk2KGKgxQQTHopBcew9yfeCRFhvdL7jpaGatEi5iZwGGQQDVOVHUN1H\
   0YLpHQjRowJBAN+R2bvA/Nimq464ZgnelEDPqaEAZWaD3kOfhS9+vL7oqES+u5E0\
   J7kXb7ZkiSVUg9XU/8PxMKx/DAz0dUmOL+UCQH8C9ETUMI2uEbqHbBdVUGNk364C\
   DFcndSxVh+34KqJdjiYSx6VPPv26X9m7S0OydTkSgs3/4ooPxo8HaMqXm80CQB+r\
   xbB3UlpOohcBwFK9mTrlMB6Cs9ql66KgwnlL9ukEhHHYozGatdXeoBCyhUsogdSU\
   6/aSAFcvWEGtj7/vyJECQQCCS1lKgEXoNQPqONalvYhyyMZRXFLdD4gbwRPK1uXK\
   Ypk3CkfFzOyfjeLcGPxXzq2qzuHzGTDxZ9PAepwX4RSk\
   -----END RSA PRIVATE KEY-----\
   -----BEGIN CERTIFICATE-----\
   MIIC3TCCAkagAwIBAgIBADANBgkqhkiG9w0BAQUFADBZMQswCQYDVQQGEwJVUzEL\
   MAkGA1UECAwCR0ExEDAOBgNVBAcMB0F0bGFudGExDTALBgNVBAoMBElFVEYxHDAa\
   BgNVBAMME2F0bGFudGEuZXhhbXBsZS5jb20wHhcNMDUxMDI0MDYzNjA2WhcNMDYx\
   MDI0MDYzNjA2WjBZMQswCQYDVQQGEwJVUzELMAkGA1UECAwCR0ExEDAOBgNVBAcM\
   B0F0bGFudGExDTALBgNVBAoMBElFVEYxHDAaBgNVBAMME2F0bGFudGEuZXhhbXBs\
   ZS5jb20wgZ8wDQYJKoZIhvcNAQEBBQADgY0AMIGJAoGBAM88wG0dWg+RdX5nqOrU\
   uyB9MQtVanLYFVR98kw8fTosvRwlJA5oh5XMiiPNa2lq4HsjKVkqUCMHl/jb21G6\
   hSJ50LAwspuVYCpm3p4dakI1knuU41wgTCeaHacBxwqTzcun9Ufe2ABL/jcNChfa\
   yd2diH6DznbY/PCDsQZaynPPAgMBAAGjgbQwgbEwHQYDVR0OBBYEFNmU/MrbVYcE\
   KDr/20WISrG1j1rNMIGBBgNVHSMEejB4gBTZlPzK21WHBCg6/9tFiEqxtY9azaFd\
   pFswWTELMAkGA1UEBhMCVVMxCzAJBgNVBAgMAkdBMRAwDgYDVQQHDAdBdGxhbnRh\
\
\
\
Peterson & Jennings         Standards Track                    [Page 17]\
\
RFC 4474                      SIP Identity                   August 2006\
\
\
   MQ0wCwYDVQQKDARJRVRGMRwwGgYDVQQDDBNhdGxhbnRhLmV4YW1wbGUuY29tggEA\
   MAwGA1UdEwQFMAMBAf8wDQYJKoZIhvcNAQEFBQADgYEADdQYtswBDmTSTq0mt211\
   7alm/XGFrb2zdbU0vorxRdOZ04qMyrIpXG1LEmnEOgcocyrXRBvq5p6WbZAcEQk0\
   DsE3Ve0Nc8x9nmvljW7GsMGFCnCuo4ODTf/1lGdVr9DeCzcj10YUQ3MRemDMXhY2\
   CtDisLWl7SXOORcZAi1oU9w=\
   -----END CERTIFICATE-----\
\
   A user of atlanta.example.com, Alice, wants to send an INVITE to\
   bob@biloxi.example.org.  She therefore creates the following INVITE\
   request, which she forwards to the atlanta.example.org proxy server\
   that instantiates the authentication service role:\
\
         INVITE sip:bob@biloxi.example.org SIP/2.0\
         Via: SIP/2.0/TLS pc33.atlanta.example.com;branch=z9hG4bKnashds8\
         To: Bob <sip:bob@biloxi.example.org>\
         From: Alice <sip:alice@atlanta.example.com>;tag=1928301774\
         Call-ID: a84b4c76e66710\
         CSeq: 314159 INVITE\
         Max-Forwards: 70\
         Date: Thu, 21 Feb 2002 13:02:03 GMT\
         Contact: <sip:alice@pc33.atlanta.example.com>\
         Content-Type: application/sdp\
         Content-Length: 147\
\
         v=0\
         o=UserA 2890844526 2890844526 IN IP4 pc33.atlanta.example.com\
         s=Session SDP\
         c=IN IP4 pc33.atlanta.example.com\
         t=0 0\
         m=audio 49172 RTP/AVP 0\
         a=rtpmap:0 PCMU/8000\
\
   When the authentication service receives the INVITE, it authenticates\
   Alice by sending a 407 response.  As a result, Alice adds an\
   Authorization header to her request, and resends to the\
   atlanta.example.com authentication service.  Now that the service is\
   sure of Alice's identity, it calculates an Identity header for the\
   request.  The canonical string over which the identity signature will\
   be generated is the following (note that the first line wraps because\
   of RFC editorial conventions):\
\
   sip:alice@atlanta.example.com|sip:bob@biloxi.example.org|\
   a84b4c76e66710|314159 INVITE|Thu, 21 Feb 2002 13:02:03 GMT|\
   sip:alice@pc33.atlanta.example.com|v=0\
   o=UserA 2890844526 2890844526 IN IP4 pc33.atlanta.example.com\
   s=Session SDP\
   c=IN IP4 pc33.atlanta.example.com\
   t=0 0\
\
\
\
Peterson & Jennings         Standards Track                    [Page 18]\
\
RFC 4474                      SIP Identity                   August 2006\
\
\
   m=audio 49172 RTP/AVP 0\
   a=rtpmap:0 PCMU/8000\
\
   The resulting signature (sha1WithRsaEncryption) using the private RSA\
   key given above, with base64 encoding, is the following:\
\
   ZYNBbHC00VMZr2kZt6VmCvPonWJMGvQTBDqghoWeLxJfzB2a1pxAr3VgrB0SsSAa\
   ifsRdiOPoQZYOy2wrVghuhcsMbHWUSFxI6p6q5TOQXHMmz6uEo3svJsSH49thyGn\
   FVcnyaZ++yRlBYYQTLqWzJ+KVhPKbfU/pryhVn9Yc6U=\
\
   Accordingly, the atlanta.example.com authentication service will\
   create an Identity header containing that base64 signature string\
   (175 bytes).  It will also add an HTTPS URL where its certificate is\
   made available.  With those two headers added, the message looks like\
   the following:\
\
   INVITE sip:bob@biloxi.example.org SIP/2.0\
   Via: SIP/2.0/TLS pc33.atlanta.example.com;branch=z9hG4bKnashds8\
   To: Bob <sip:bob@biloxi.example.org>\
   From: Alice <sip:alice@atlanta.example.com>;tag=1928301774\
   Call-ID: a84b4c76e66710\
   CSeq: 314159 INVITE\
   Max-Forwards: 70\
   Date: Thu, 21 Feb 2002 13:02:03 GMT\
   Contact: <sip:alice@pc33.atlanta.example.com>\
   Identity:\
     "ZYNBbHC00VMZr2kZt6VmCvPonWJMGvQTBDqghoWeLxJfzB2a1pxAr3VgrB0SsSAa\
      ifsRdiOPoQZYOy2wrVghuhcsMbHWUSFxI6p6q5TOQXHMmz6uEo3svJsSH49thyGn\
      FVcnyaZ++yRlBYYQTLqWzJ+KVhPKbfU/pryhVn9Yc6U="\
   Identity-Info: <https://atlanta.example.com/atlanta.cer>;alg=rsa-sha1\
   Content-Type: application/sdp\
   Content-Length: 147\
\
   v=0\
   o=UserA 2890844526 2890844526 IN IP4 pc33.atlanta.example.com\
   s=Session SDP\
   c=IN IP4 pc33.atlanta.example.com\
   t=0 0\
   m=audio 49172 RTP/AVP 0\
   a=rtpmap:0 PCMU/8000\
\
   atlanta.example.com then forwards the request normally.  When Bob\
   receives the request, if he does not already know the certificate of\
   atlanta.example.com, he dereferences the URL in the Identity-Info\
   header to acquire the certificate.  Bob then generates the same\
   canonical string given above, from the same headers of the SIP\
   request.  Using this canonical string, the signed digest in the\
   Identity header, and the certificate discovered by dereferencing the\
\
\
\
Peterson & Jennings         Standards Track                    [Page 19]\
\
RFC 4474                      SIP Identity                   August 2006\
\
\
   Identity-Info header, Bob can verify that the given set of headers\
   and the message body have not been modified.\
\
10.2.  Identity for a Request with No MIME Body or Contact\
\
   Consider the following private key and certificate pair assigned to\
   "biloxi.example.org".\
\
   -----BEGIN RSA PRIVATE KEY-----\
   MIICXgIBAAKBgQC/obBYLRMPjskrAqWOiGPAUxI3/m2ti7ix4caqCTAuFX5cLegQ\
   7nmquLOHfIhxVIqT2f06UA0lOo2NVofK9G7MTkVbVNiyAlLYUDEj7XWLDICf3ZHL\
   6Fr/+CF7wrQ9r4kv7XiJKxodVCCd/DhCT9Gp+VDoe8HymqOW/KsneriyIwIDAQAB\
   AoGBAJ7fsFIKXKkjWgj8ksGOthS3Sn19xPSCyEdBxfEm2Pj7/Nzzeli/PcOaic0k\
   JALBcnqN2fHEeIGK/9xUBxTufgQYVJqvyHERs6rXX/iT4Ynm9t1905EiQ9ZpHsrI\
   /AMMUYA1QrGgAIHvZLVLzq+9KLDEZ+HQbuCLJXF+6bl0Eb5BAkEA636oMANp0Qa3\
   mYWEQ2utmGsYxkXSfyBb18TCOwCty0ndBR24zyOJF2NbZS98Lz+Ga25hfIGw/JHK\
   nD9bOE88UwJBANBRSpd4bmS+m48R/13tRESAtHqydNinX0kS/RhwHr7mkHTU3k/M\
   FxQtx34I3GKzaZxMn0A66KS9v/SHdnF+ePECQQCGe7QshyZ8uitLPtZDclCWhEKH\
   qAQHmUEZvUF2VHLrbukLLOgHUrHNa24cILv4d3yaCVUetymNcuyTwhKj24wFAkAO\
   z/jx1EplN3hwL+NsllZoWI58uvu7/Aq2c3czqaVGBbb317sHCYgKk0bAG3kwO3mi\
   93/LXWT1cdiYVpmBcHDBAkEAmpgkFj+xZu5gWASY5ujv+FCMP0WwaH5hTnXu+tKe\
   PJ3d2IJZKxGnl6itKRN7GeRh9PSK0kZSqGFeVrvsJ4Nopg==\
   -----END RSA PRIVATE KEY-----\
   -----BEGIN CERTIFICATE-----\
   MIIC1jCCAj+gAwIBAgIBADANBgkqhkiG9w0BAQUFADBXMQswCQYDVQQGEwJVUzEL\
   MAkGA1UECAwCTVMxDzANBgNVBAcMBkJpbG94aTENMAsGA1UECgwESUVURjEbMBkG\
   A1UEAwwSYmlsb3hpLmV4YW1wbGUuY29tMB4XDTA1MTAyNDA2NDAyNloXDTA2MTAy\
   NDA2NDAyNlowVzELMAkGA1UEBhMCVVMxCzAJBgNVBAgMAk1TMQ8wDQYDVQQHDAZC\
   aWxveGkxDTALBgNVBAoMBElFVEYxGzAZBgNVBAMMEmJpbG94aS5leGFtcGxlLmNv\
   bTCBnzANBgkqhkiG9w0BAQEFAAOBjQAwgYkCgYEAv6GwWC0TD47JKwKljohjwFMS\
   N/5trYu4seHGqgkwLhV+XC3oEO55qrizh3yIcVSKk9n9OlANJTqNjVaHyvRuzE5F\
   W1TYsgJS2FAxI+11iwyAn92Ry+ha//ghe8K0Pa+JL+14iSsaHVQgnfw4Qk/RqflQ\
   6HvB8pqjlvyrJ3q4siMCAwEAAaOBsTCBrjAdBgNVHQ4EFgQU0Z+RL47W/APDtc5B\
   fSoQXuEFE/wwfwYDVR0jBHgwdoAU0Z+RL47W/APDtc5BfSoQXuEFE/yhW6RZMFcx\
   CzAJBgNVBAYTAlVTMQswCQYDVQQIDAJNUzEPMA0GA1UEBwwGQmlsb3hpMQ0wCwYD\
   VQQKDARJRVRGMRswGQYDVQQDDBJiaWxveGkuZXhhbXBsZS5jb22CAQAwDAYDVR0T\
   BAUwAwEB/zANBgkqhkiG9w0BAQUFAAOBgQBiyKHIt8TXfGNfpnJXi5jCizOxmY8Y\
   gln8tyPFaeyq95TGcvTCWzdoBLVpBD+fpRWrX/II5sE6VHbbAPjjVmKbZwzQAtpp\
   P2Fauj28t94ZeDHN2vqzjfnHjCO24kG3Juf2T80ilp9YHcDwxjUFrt86UnlC+yid\
   yaTeusW5Gu7v1g==\
   -----END CERTIFICATE-----\
\
   Bob (bob@biloxi.example.org) now wants to send a BYE request to Alice\
   at the end of the dialog initiated in the previous example.  He\
   therefore creates the following BYE request, which he forwards to the\
   'biloxi.example.org' proxy server that instantiates the\
   authentication service role:\
\
\
\
\
Peterson & Jennings         Standards Track                    [Page 20]\
\
RFC 4474                      SIP Identity                   August 2006\
\
\
   BYE sip:alice@pc33.atlanta.example.com SIP/2.0\
   Via: SIP/2.0/TLS 192.0.2.4;branch=z9hG4bKnashds10\
   Max-Forwards: 70\
   From: Bob <sip:bob@biloxi.example.org>;tag=a6c85cf\
   To: Alice <sip:alice@atlanta.example.com>;tag=1928301774\
   Call-ID: a84b4c76e66710\
   CSeq: 231 BYE\
   Content-Length: 0\
\
   When the authentication service receives the BYE, it authenticates\
   Bob by sending a 407 response.  As a result, Bob adds an\
   Authorization header to his request, and resends to the\
   biloxi.example.org authentication service.  Now that the service is\
   sure of Bob's identity, it prepares to calculate an Identity header\
   for the request.  Note that this request does not have a Date header\
   field.  Accordingly, the biloxi.example.org will add a Date header to\
   the request before calculating the identity signature.  If the\
   Content-Length header were not present, the authentication service\
   would add it as well.  The baseline message is thus:\
\
   BYE sip:alice@pc33.atlanta.example.com SIP/2.0\
   Via: SIP/2.0/TLS 192.0.2.4;branch=z9hG4bKnashds10\
   Max-Forwards: 70\
   From: Bob <sip:bob@biloxi.example.org>;tag=a6c85cf\
   To: Alice <sip:alice@atlanta.example.com>;tag=1928301774\
   Date: Thu, 21 Feb 2002 14:19:51 GMT\
   Call-ID: a84b4c76e66710\
   CSeq: 231 BYE\
   Content-Length: 0\
\
   Also note that this request contains no Contact header field.\
   Accordingly, biloxi.example.org will place no value in the canonical\
   string for the addr-spec of the Contact address.  Also note that\
   there is no message body, and accordingly, the signature string will\
   terminate, in this case, with two vertical bars.  The canonical\
   string over which the identity signature will be generated is the\
   following (note that the first line wraps because of RFC editorial\
   conventions):\
\
   sip:bob@biloxi.example.org|sip:alice@atlanta.example.com|\
   a84b4c76e66710|231 BYE|Thu, 21 Feb 2002 14:19:51 GMT||\
\
   The resulting signature (sha1WithRsaEncryption) using the private RSA\
   key given above for biloxi.example.org, with base64 encoding, is the\
   following:\
\
\
\
\
\
\
Peterson & Jennings         Standards Track                    [Page 21]\
\
RFC 4474                      SIP Identity                   August 2006\
\
\
   sv5CTo05KqpSmtHt3dcEiO/1CWTSZtnG3iV+1nmurLXV/HmtyNS7Ltrg9dlxkWzo\
   eU7d7OV8HweTTDobV3itTmgPwCFjaEmMyEI3d7SyN21yNDo2ER/Ovgtw0Lu5csIp\
   pPqOg1uXndzHbG7mR6Rl9BnUhHufVRbp51Mn3w0gfUs=\
\
   Accordingly, the biloxi.example.org authentication service will\
   create an Identity header containing that base64 signature string.\
   It will also add an HTTPS URL where its certificate is made\
   available.  With those two headers added, the message looks like the\
   following:\
\
   BYE sip:alice@pc33.atlanta.example.com SIP/2.0\
   Via: SIP/2.0/TLS 192.0.2.4;branch=z9hG4bKnashds10\
   Max-Forwards: 70\
   From: Bob <sip:bob@biloxi.example.org>;tag=a6c85cf\
   To: Alice <sip:alice@atlanta.example.com>;tag=1928301774\
   Date: Thu, 21 Feb 2002 14:19:51 GMT\
   Call-ID: a84b4c76e66710\
   CSeq: 231 BYE\
   Identity:\
     "sv5CTo05KqpSmtHt3dcEiO/1CWTSZtnG3iV+1nmurLXV/HmtyNS7Ltrg9dlxkWzo\
      eU7d7OV8HweTTDobV3itTmgPwCFjaEmMyEI3d7SyN21yNDo2ER/Ovgtw0Lu5csIp\
      pPqOg1uXndzHbG7mR6Rl9BnUhHufVRbp51Mn3w0gfUs="\
   Identity-Info: <https://biloxi.example.org/biloxi.cer>;alg=rsa-sha1\
   Content-Length: 0\
\
   biloxi.example.org then forwards the request normally.\
\
11.  Identity and the TEL URI Scheme\
\
   Since many SIP applications provide a Voice over IP (VoIP) service,\
   telephone numbers are commonly used as identities in SIP deployments.\
   In the majority of cases, this is not problematic for the identity\
   mechanism described in this document.  Telephone numbers commonly\
   appear in the username portion of a SIP URI (e.g.,\
   'sip:+17005551008@chicago.example.com;user=phone').  That username\
   conforms to the syntax of the TEL URI scheme (RFC 3966 [13]).  For\
   this sort of SIP address-of-record, chicago.example.com is the\
   appropriate signatory.\
\
   It is also possible for a TEL URI to appear in the SIP To or From\
   header field outside the context of a SIP or SIPS URI (e.g.,\
   'tel:+17005551008').  In this case, it is much less clear which\
   signatory is appropriate for the identity.  Fortunately for the\
   identity mechanism, this form of the TEL URI is more common for the\
   To header field and Request-URI in SIP than in the From header field,\
   since the UAC has no option but to provide a TEL URI alone when the\
   remote domain to which a request is sent is unknown.  The local\
   domain, however, is usually known by the UAC, and accordingly it can\
\
\
\
Peterson & Jennings         Standards Track                    [Page 22]\
\
RFC 4474                      SIP Identity                   August 2006\
\
\
   form a proper From header field containing a SIP URI with a username\
   in TEL URI form.  Implementations that intend to send their requests\
   through an authentication service SHOULD put telephone numbers in the\
   From header field into SIP or SIPS URIs whenever possible.\
\
   If the local domain is unknown to a UAC formulating a request, it\
   most likely will not be able to locate an authentication service for\
   its request, and therefore the question of providing identity in\
   these cases is somewhat moot.  However, an authentication service MAY\
   sign a request containing a TEL URI in the From header field.  This\
   is permitted in this specification strictly for forward compatibility\
   purposes.  In the longer-term, it is possible that ENUM [14] may\
   provide a way to determine which administrative domain is responsible\
   for a telephone number, and this may aid in the signing and\
   verification of SIP identities that contain telephone numbers.  This\
   is a subject for future work.\
\
12.  Privacy Considerations\
\
   The identity mechanism presented in this document is compatible with\
   the standard SIP practices for privacy described in RFC 3323 [3].  A\
   SIP proxy server can act both as a privacy service and as an\
   authentication service.  Since a user agent can provide any From\
   header field value that the authentication service is willing to\
   authorize, there is no reason why private SIP URIs that contain\
   legitimate domains (e.g., sip:anonymous@example.com) cannot be signed\
   by an authentication service.  The construction of the Identity\
   header is the same for private URIs as it is for any other sort of\
   URIs.\
\
   Note, however, that an authentication service must possess a\
   certificate corresponding to the host portion of the addr-spec of the\
   From header field of any request that it signs; accordingly, using\
   domains like 'anonymous.invalid' will not be possible for privacy\
   services that also act as authentication services.  The assurance\
   offered by the usage of anonymous URIs with a valid domain portion is\
   "this is a known user in my domain that I have authenticated, but I\
   am keeping its identity private".  The use of the domain\
   'anonymous.invalid' entails that no corresponding authority for the\
   domain can exist, and as a consequence, authentication service\
   functions are meaningless.\
\
   The "header" level of privacy described in RFC 3323 requests that a\
   privacy service alter the Contact header field value of a SIP\
   message.  Since the Contact header field is protected by the\
   signature in an Identity header, privacy services cannot be applied\
   after authentication services without a resulting integrity\
   violation.\
\
\
\
Peterson & Jennings         Standards Track                    [Page 23]\
\
RFC 4474                      SIP Identity                   August 2006\
\
\
   RFC 3325 [12] defines the "id" priv-value token, which is specific to\
   the P-Asserted-Identity header.  The sort of assertion provided by\
   the P-Asserted-Identity header is very different from the Identity\
   header presented in this document.  It contains additional\
   information about the sender of a message that may go beyond what\
   appears in the From header field; P-Asserted-Identity holds a\
   definitive identity for the sender that is somehow known to a closed\
   network of intermediaries that presumably the network will use this\
   identity for billing or security purposes.  The danger of this\
   network-specific information leaking outside of the closed network\
   motivated the "id" priv-value token.  The "id" priv-value token has\
   no implications for the Identity header, and privacy services MUST\
   NOT remove the Identity header when a priv-value of "id" appears in a\
   Privacy header.\
\
   Finally, note that unlike RFC 3325, the mechanism described in this\
   specification adds no information to SIP requests that has privacy\
   implications.\
\
13.  Security Considerations\
\
13.1.  Handling of digest-string Elements\
\
   This document describes a mechanism that provides a signature over\
   the Contact, Date, Call-ID, CSeq, To, and From header fields of SIP\
   requests.  While a signature over the From header field would be\
   sufficient to secure a URI alone, the additional headers provide\
   replay protection and reference integrity necessary to make sure that\
   the Identity header will not be used in cut-and-paste attacks.  In\
   general, the considerations related to the security of these headers\
   are the same as those given in RFC 3261 for including headers in\
   tunneled 'message/sip' MIME bodies (see Section 23 in particular).\
   The following section details the individual security properties\
   obtained by including each of these header fields within the\
   signature; collectively, this set of header fields provides the\
   necessary properties to prevent impersonation.\
\
   The From header field indicates the identity of the sender of the\
   message, and the SIP address-of-record URI in the From header field\
   is the identity of a SIP user, for the purposes of this document.\
   The To header field provides the identity of the SIP user that this\
   request targets.  Providing the To header field in the Identity\
   signature serves two purposes: first, it prevents cut-and-paste\
   attacks in which an Identity header from legitimate request for one\
   user is cut-and-pasted into a request for a different user; second,\
   it preserves the starting URI scheme of the request, which helps\
   prevent downgrade attacks against the use of SIPS.\
\
\
\
\
Peterson & Jennings         Standards Track                    [Page 24]\
\
RFC 4474                      SIP Identity                   August 2006\
\
\
   The Date and Contact headers provide reference integrity and replay\
   protection, as described in RFC 3261, Section 23.4.2.\
   Implementations of this specification MUST NOT deem valid a request\
   with an outdated Date header field (the RECOMMENDED interval is that\
   the Date header must indicate a time within 3600 seconds of the\
   receipt of a message).  Implementations MUST also record Call-IDs\
   received in valid requests containing an Identity header, and MUST\
   remember those Call-IDs for at least the duration of a single Date\
   interval (i.e., commonly 3600 seconds).  Because a SIP-compliant UA\
   never generates the same Call-ID twice, verifiers can use the Call-ID\
   to recognize cut-and-paste attacks; the Call-ID serves as a nonce.\
   The result of this is that if an Identity header is replayed within\
   the Date interval, verifiers will recognize that it is invalid\
   because of a Call-ID duplication; if an Identity header is replayed\
   after the Date interval, verifiers will recognize that it is invalid\
   because the Date is stale.  The CSeq header field contains a numbered\
   identifier for the transaction, and the name of the method of the\
   request; without this information, an INVITE request could be cut-\
   and-pasted by an attacker and transformed into a BYE request without\
   changing any fields covered by the Identity header, and moreover\
   requests within a certain transaction could be replayed in\
   potentially confusing or malicious ways.\
\
   The Contact header field is included to tie the Identity header to a\
   particular user agent instance that generated the request.  Were an\
   active attacker to intercept a request containing an Identity header,\
   and cut-and-paste the Identity header field into its own request\
   (reusing the From, To, Contact, Date, and Call-ID fields that appear\
   in the original message), the attacker would not be eligible to\
   receive SIP requests from the called user agent, since those requests\
   are routed to the URI identified in the Contact header field.\
   However, the Contact header is only included in dialog-forming\
   requests, so it does not provide this protection in all cases.\
\
   It might seem attractive to provide a signature over some of the\
   information present in the Via header field value(s).  For example,\
   without a signature over the sent-by field of the topmost Via header,\
   an attacker could remove that Via header and insert its own in a\
   cut-and-paste attack, which would cause all responses to the request\
   to be routed to a host of the attacker's choosing.  However, a\
   signature over the topmost Via header does not prevent attacks of\
   this nature, since the attacker could leave the topmost Via intact\
   and merely insert a new Via header field directly after it, which\
   would cause responses to be routed to the attacker's host "on their\
   way" to the valid host, which has exactly the same end result.\
   Although it is possible that an intermediary-based authentication\
   service could guarantee that no Via hops are inserted between the\
   sending user agent and the authentication service, it could not\
\
\
\
Peterson & Jennings         Standards Track                    [Page 25]\
\
RFC 4474                      SIP Identity                   August 2006\
\
\
   prevent an attacker from adding a Via hop after the authentication\
   service, and thereby preempting responses.  It is necessary for the\
   proper operation of SIP for subsequent intermediaries to be capable\
   of inserting such Via header fields, and thus it cannot be prevented.\
   As such, though it is desirable, securing Via is not possible through\
   the sort of identity mechanism described in this document; the best\
   known practice for securing Via is the use of SIPS.\
\
   This mechanism also provides a signature over the bodies of SIP\
   requests.  The most important reason for doing so is to protect\
   Session Description Protocol (SDP) bodies carried in SIP requests.\
   There is little purpose in establishing the identity of the user that\
   originated a SIP request if this assurance is not coupled with a\
   comparable assurance over the media descriptors.  Note, however, that\
   this is not perfect end-to-end security.  The authentication service\
   itself, when instantiated at a intermediary, could conceivably change\
   the SDP (and SIP headers, for that matter) before providing a\
   signature.  Thus, while this mechanism reduces the chance that a\
   replayer or man-in-the-middle will modify SDP, it does not eliminate\
   it entirely.  Since it is a foundational assumption of this mechanism\
   that the users trust their local domain to vouch for their security,\
   they must also trust the service not to violate the integrity of\
   their message without good reason.  Note that RFC 3261, Section 16.6,\
   states that SIP proxy servers "MUST NOT add to, modify, or remove the\
   message body."\
\
   In the end analysis, the Identity and Identity-Info headers cannot\
   protect themselves.  Any attacker could remove these headers from a\
   SIP request, and modify the request arbitrarily afterwards.  However,\
   this mechanism is not intended to protect requests from men-in-the-\
   middle who interfere with SIP messages; it is intended only to\
   provide a way that SIP users can prove definitively that they are who\
   they claim to be.  At best, by stripping identity information from a\
   request, a man-in-the-middle could make it impossible to distinguish\
   any illegitimate messages he would like to send from those messages\
   sent by an authorized user.  However, it requires a considerably\
   greater amount of energy to mount such an attack than it does to\
   mount trivial impersonations by just copying someone else's From\
   header field.  This mechanism provides a way that an authorized user\
   can provide a definitive assurance of his identity that an\
   unauthorized user, an impersonator, cannot.\
\
   One additional respect in which the Identity-Info header cannot\
   protect itself is the 'alg' parameter.  The 'alg' parameter is not\
   included in the digest-string, and accordingly, a man-in-the-middle\
   might attempt to modify the 'alg' parameter.  However, it is\
   important to note that preventing men-in-the-middle is not the\
   primary impetus for this mechanism.  Moreover, changing the 'alg'\
\
\
\
Peterson & Jennings         Standards Track                    [Page 26]\
\
RFC 4474                      SIP Identity                   August 2006\
\
\
   would at worst result in some sort of bid-down attack, and at best\
   cause a failure in the verifier.  Note that only one valid 'alg'\
   parameter is defined in this document and that thus there is\
   currently no weaker algorithm to which the mechanism can be bid down.\
   'alg' has been incorporated into this mechanism for forward-\
   compatibility reasons in case the current algorithm exhibits\
   weaknesses, and requires swift replacement, in the future.\
\
13.2.  Display-Names and Identity\
\
   As a matter of interface design, SIP user agents might render the\
   display-name portion of the From header field of a caller as the\
   identity of the caller; there is a significant precedent in email\
   user interfaces for this practice.  As such, it might seem that the\
   lack of a signature over the display-name is a significant omission.\
\
   However, there are several important senses in which a signature over\
   the display-name does not prevent impersonation.  In the first place,\
   a particular display-name, like "Jon Peterson", is not unique in the\
   world; many users in different administrative domains might\
   legitimately claim that name.  Furthermore, enrollment practices for\
   SIP-based services might have a difficult time discerning the\
   legitimate display-name for a user; it is safe to assume that\
   impersonators will be capable of creating SIP accounts with arbitrary\
   display-names.  The same situation prevails in email today.  Note\
   that an impersonator who attempted to replay a message with an\
   Identity header, changing only the display-name in the From header\
   field, would be detected by the other replay protection mechanisms\
   described in Section 13.1.\
\
   Of course, an authentication service can enforce policies about the\
   display-name even if the display-name is not signed.  The exact\
   mechanics for creating and operationalizing such policies is outside\
   the scope of this document.  The effect of this policy would not be\
   to prevent impersonation of a particular unique identifier like a SIP\
   URI (since display-names are not unique identifiers), but to allow a\
   domain to manage the claims made by its users.  If such policies are\
   enforced, users would not be free to claim any display-name of their\
   choosing.  In the absence of a signature, man-in-the-middle attackers\
   could conceivably alter the display-names in a request with impunity.\
   Note that the scope of this specification is impersonation attacks,\
   however, and that a man-in-the-middle might also strip the Identity\
   and Identity-Info headers from a message.\
\
   There are many environments in which policies regarding the display-\
   name aren't feasible.  Distributing bit-exact and internationalizable\
   display-names to end-users as part of the enrollment or registration\
   process would require mechanisms that are not explored in this\
\
\
\
Peterson & Jennings         Standards Track                    [Page 27]\
\
RFC 4474                      SIP Identity                   August 2006\
\
\
   document.  In the absence of policy enforcement regarding domain\
   names, there are conceivably attacks that an adversary could mount\
   against SIP systems that rely too heavily on the display-name in\
   their user interface, but this argues for intelligent interface\
   design, not changes to the mechanisms.  Relying on a non-unique\
   identifier for identity would ultimately result in a weak mechanism.\
\
13.3.  Securing the Connection to the Authentication Service\
\
   The assurance provided by this mechanism is strongest when a user\
   agent forms a direct connection, preferably one secured by TLS, to an\
   intermediary-based authentication service.  The reasons for this are\
   twofold:\
\
      If a user does not receive a certificate from the authentication\
      service over this TLS connection that corresponds to the expected\
      domain (especially when the user receives a challenge via a\
      mechanism such as Digest), then it is possible that a rogue server\
      is attempting to pose as an authentication service for a domain\
      that it does not control, possibly in an attempt to collect shared\
      secrets for that domain.\
\
      Without TLS, the various header field values and the body of the\
      request will not have integrity protection when the request\
      arrives at an authentication service.  Accordingly, a prior\
      legitimate or illegitimate intermediary could modify the message\
      arbitrarily.\
\
   Of these two concerns, the first is most material to the intended\
   scope of this mechanism.  This mechanism is intended to prevent\
   impersonation attacks, not man-in-the-middle attacks; integrity over\
   the header and bodies is provided by this mechanism only to prevent\
   replay attacks.  However, it is possible that applications relying on\
   the presence of the Identity header could leverage this integrity\
   protection, especially body integrity, for services other than replay\
   protection.\
\
   Accordingly, direct TLS connections SHOULD be used between the UAC\
   and the authentication service whenever possible.  The opportunistic\
   nature of this mechanism, however, makes it very difficult to\
   constrain UAC behavior, and moreover there will be some deployment\
   architectures where a direct connection is simply infeasible and the\
   UAC cannot act as an authentication service itself.  Accordingly,\
   when a direct connection and TLS are not possible, a UAC should use\
   the SIPS mechanism, Digest 'auth-int' for body integrity, or both\
   when it can.  The ultimate decision to add an Identity header to a\
\
\
\
\
\
Peterson & Jennings         Standards Track                    [Page 28]\
\
RFC 4474                      SIP Identity                   August 2006\
\
\
   request lies with the authentication service, of course; domain\
   policy must identify those cases where the UAC's security association\
   with the authentication service is too weak.\
\
13.4.  Domain Names and Subordination\
\
   When a verifier processes a request containing an Identity-Info\
   header, it must compare the domain portion of the URI in the From\
   header field of the request with the domain name that is the subject\
   of the certificate acquired from the Identity-Info header.  While it\
   might seem that this should be a straightforward process, it is\
   complicated by two deployment realities.  In the first place,\
   certificates have varying ways of describing their subjects, and may\
   indeed have multiple subjects, especially in 'virtual hosting' cases\
   where multiple domains are managed by a single application.\
   Secondly, some SIP services may delegate SIP functions to a\
   subordinate domain and utilize the procedures in RFC 3263 [4] that\
   allow requests for, say, 'example.com' to be routed to\
   'sip.example.com'.  As a result, a user with the AoR\
   'sip:jon@example.com' may process its requests through a host like\
   'sip.example.com', and it may be that latter host that acts as an\
   authentication service.\
\
   To meet the second of these problems, a domain that deploys an\
   authentication service on a subordinate host MUST be willing to\
   supply that host with the private keying material associated with a\
   certificate whose subject is a domain name that corresponds to the\
   domain portion of the AoRs that the domain distributes to users.\
   Note that this corresponds to the comparable case of routing inbound\
   SIP requests to a domain.  When the NAPTR and SRV procedures of RFC\
   3263 are used to direct requests to a domain name other than the\
   domain in the original Request-URI (e.g., for 'sip:jon@example.com',\
   the corresponding SRV records point to the service\
   'sip1.example.org'), the client expects that the certificate passed\
   back in any TLS exchange with that host will correspond exactly with\
   the domain of the original Request-URI, not the domain name of the\
   host.  Consequently, in order to make inbound routing to such SIP\
   services work, a domain administrator must similarly be willing to\
   share the domain's private key with the service.  This design\
   decision was made to compensate for the insecurity of the DNS, and it\
   makes certain potential approaches to DNS-based 'virtual hosting'\
   unsecurable for SIP in environments where domain administrators are\
   unwilling to share keys with hosting services.\
\
   A verifier MUST evaluate the correspondence between the user's\
   identity and the signing certificate by following the procedures\
   defined in RFC 2818 [11], Section 3.1.  While RFC 2818 deals with the\
   use of HTTP in TLS, the procedures described are applicable to\
\
\
\
Peterson & Jennings         Standards Track                    [Page 29]\
\
RFC 4474                      SIP Identity                   August 2006\
\
\
   verifying identity if one substitutes the "hostname of the server" in\
   HTTP for the domain portion of the user's identity in the From header\
   field of a SIP request with an Identity header.\
\
   Because the domain certificates that can be used by authentication\
   services need to assert only the hostname of the authentication\
   service, existing certificate authorities can provide adequate\
   certificates for this mechanism.  However, not all proxy servers and\
   user agents will be able to support the root certificates of all\
   certificate authorities, and moreover there are some significant\
   differences in the policies by which certificate authorities issue\
   their certificates.  This document makes no recommendations for the\
   usage of particular certificate authorities, nor does it describe any\
   particular policies that certificate authorities should follow, but\
   it is anticipated that operational experience will create de facto\
   standards for authentication services.  Some federations of service\
   providers, for example, might only trust certificates that have been\
   provided by a certificate authority operated by the federation.  It\
   is strongly RECOMMENDED that self-signed domain certificates should\
   not be trusted by verifiers, unless some previous key exchange has\
   justified such trust.\
\
   For further information on certificate security and practices, see\
   RFC 3280 [9].  The Security Considerations of RFC 3280 are applicable\
   to this document.\
\
13.5.  Authorization and Transitional Strategies\
\
   Ultimately, the worth of an assurance provided by an Identity header\
   is limited by the security practices of the domain that issues the\
   assurance.  Relying on an Identity header generated by a remote\
   administrative domain assumes that the issuing domain used its\
   administrative practices to authenticate its users.  However, it is\
   possible that some domains will implement policies that effectively\
   make users unaccountable (e.g., ones that accept unauthenticated\
   registrations from arbitrary users).  The value of an Identity header\
   from such domains is questionable.  While there is no magic way for a\
   verifier to distinguish "good" from "bad" domains by inspecting a SIP\
   request, it is expected that further work in authorization practices\
   could be built on top of this identity solution; without such an\
   identity solution, many promising approaches to authorization policy\
   are impossible.  That much said, it is RECOMMENDED that\
   authentication services based on proxy servers employ strong\
   authentication practices such as token-based identifiers.\
\
   One cannot expect the Identity and Identity-Info headers to be\
   supported by every SIP entity overnight.  This leaves the verifier in\
   a compromising position; when it receives a request from a given SIP\
\
\
\
Peterson & Jennings         Standards Track                    [Page 30]\
\
RFC 4474                      SIP Identity                   August 2006\
\
\
   user, how can it know whether or not the sender's domain supports\
   Identity?  In the absence of ubiquitous support for identity, some\
   transitional strategies are necessary.\
\
      A verifier could remember when it receives a request from a domain\
      that uses Identity, and in the future, view messages received from\
      that domain without Identity headers with skepticism.\
\
      A verifier could query the domain through some sort of callback\
      system to determine whether or not it is running an authentication\
      service.  There are a number of potential ways in which this could\
      be implemented; use of the SIP OPTIONS method is one possibility.\
      This is left as a subject for future work.\
\
   In the long term, some sort of identity mechanism, either the one\
   documented in this specification or a successor, must become\
   mandatory-to-use for the SIP protocol; that is the only way to\
   guarantee that this protection can always be expected by verifiers.\
\
   Finally, it is worth noting that the presence or absence of the\
   Identity headers cannot be the sole factor in making an authorization\
   decision.  Permissions might be granted to a message on the basis of\
   the specific verified Identity or really on any other aspect of a SIP\
   request.  Authorization policies are outside the scope of this\
   specification, but this specification advises any future\
   authorization work not to assume that messages with valid Identity\
   headers are always good.\
\
14.  IANA Considerations\
\
   This document requests changes to the header and response-code sub-\
   registries of the SIP parameters IANA registry, and requests the\
   creation of two new registries for parameters for the Identity-Info\
   header.\
\
14.1.  Header Field Names\
\
   This document specifies two new SIP headers: Identity and Identity-\
   Info.  Their syntax is given in Section 9.  These headers are defined\
   by the following information, which has been added to the header\
   sub-registry under http://www.iana.org/assignments/sip-parameters.\
\
         Header Name: Identity\
         Compact Form: y\
         Header Name: Identity-Info\
         Compact Form: n\
\
\
\
\
\
Peterson & Jennings         Standards Track                    [Page 31]\
\
RFC 4474                      SIP Identity                   August 2006\
\
\
14.2.  428 'Use Identity Header' Response Code\
\
   This document registers a new SIP response code, which is described\
   in Section 6.  It is sent when a verifier receives a SIP request that\
   lacks an Identity header in order to indicate that the request should\
   be re-sent with an Identity header.  This response code is defined by\
   the following information, which has been added to the method and\
   response-code sub-registry under\
   http://www.iana.org/assignments/sip-parameters.\
\
         Response Code Number: 428\
         Default Reason Phrase: Use Identity Header\
\
14.3.  436 'Bad Identity-Info' Response Code\
\
   This document registers a new SIP response code, which is described\
   in Section 6.  It is used when the Identity-Info header contains a\
   URI that cannot be dereferenced by the verifier (either the URI\
   scheme is unsupported by the verifier, or the resource designated by\
   the URI is otherwise unavailable).  This response code is defined by\
   the following information, which has been added to the method and\
   response-code sub-registry under\
   http://www.iana.org/assignments/sip-parameters.\
\
         Response Code Number: 436\
         Default Reason Phrase: Bad Identity-Info\
\
14.4.  437 'Unsupported Certificate' Response Code\
\
   This document registers a new SIP response code, which is described\
   in Section 6.  It is used when the verifier cannot validate the\
   certificate referenced by the URI of the Identity-Info header,\
   because, for example, the certificate is self-signed, or signed by a\
   root certificate authority for whom the verifier does not possess a\
   root certificate.  This response code is defined by the following\
   information, which has been added to the method and response-code\
   sub-registry under http://www.iana.org/assignments/sip-parameters.\
\
         Response Code Number: 437\
         Default Reason Phrase: Unsupported Certificate\
\
\
\
\
\
\
\
\
\
\
\
Peterson & Jennings         Standards Track                    [Page 32]\
\
RFC 4474                      SIP Identity                   August 2006\
\
\
14.5.  438 'Invalid Identity Header' Response Code\
\
   This document registers a new SIP response code, which is described\
   in Section 6.  It is used when the verifier receives a message with\
   an Identity signature that does not correspond to the digest-string\
   calculated by the verifier.  This response code is defined by the\
   following information, which has been added to the method and\
   response-code sub-registry under\
   http://www.iana.org/assignments/sip-parameters.\
\
         Response Code Number: 438\
         Default Reason Phrase: Invalid Identity Header\
\
14.6.  Identity-Info Parameters\
\
   The IANA has created a new registry for Identity-Info headers.  This\
   registry is to be prepopulated with a single entry for a parameter\
   called 'alg', which describes the algorithm used to create the\
   signature that appears in the Identity header.  Registry entries must\
   contain the name of the parameter and the specification in which the\
   parameter is defined.  New parameters for the Identity-Info header\
   may be defined only in Standards Track RFCs.\
\
14.7.  Identity-Info Algorithm Parameter Values\
\
   The IANA has created a new registry for Identity-Info 'alg' parameter\
   values.  This registry is to be prepopulated with a single entry for\
   a value called 'rsa-sha1', which describes the algorithm used to\
   create the signature that appears in the Identity header.  Registry\
   entries must contain the name of the 'alg' parameter value and the\
   specification in which the value is described.  New values for the\
   'alg' parameter may be defined only in Standards Track RFCs.\
\
\
\
\
\
\
\
\
\
\
\
\
\
\
\
\
\
\
\
Peterson & Jennings         Standards Track                    [Page 33]\
\
RFC 4474                      SIP Identity                   August 2006\
\
\
Appendix A.  Acknowledgements\
\
   The authors would like to thank Eric Rescorla, Rohan Mahy, Robert\
   Sparks, Jonathan Rosenberg, Mark Watson, Henry Sinnreich, Alan\
   Johnston, Patrik Faltstrom, Paul Kyzviat, Adam Roach, John Elwell,\
   Aki Niemi, and Jim Schaad for their comments.  Jonathan Rosenberg\
   provided detailed fixes to innumerable sections of the document.  The\
   bit-archive presented in Appendix B follows the pioneering example of\
   RFC 4475 [16].  Thanks to Hans Persson and Tao Wan for thorough nit\
   reviews.\
\
Appendix B.  Bit-Exact Archive of Examples of Messages\
\
   The following text block is an encoded, gzip-compressed TAR archive\
   of files that represent the transformations performed on the examples\
   of messages discussed in Section 10.  It includes for each example:\
\
   o  (foo).message: the original message\
   o  (foo).canonical: the canonical string constructed from that\
      message\
   o  (foo).sha1: the SHA1 hash of the canonical string (hexadecimal)\
   o  (foo).signed: the RSA-signed SHA1 hash of the canonical string\
      (binary)\
   o  (foo).signed.enc: the base64 encoding of the RSA-signed SHA1 hash\
      of the canonical string as it would appear in the request\
   o  (foo).identity: the original message with the Identity and\
      Identity-Info headers added\
\
   Also included in the archive are two public key/certificate pairs,\
   for atlanta.example.com and biloxi.example.org, respectively,\
   including:\
\
   o  (foo).cer: the certificate of the domain\
   o  (foo).privkey: the private key of the domain\
   o  (foo).pubkey: the public key of the domain, extracted from the\
      cert file for convenience\
\
   To recover the compressed archive file intact, the text of this\
   document may be passed as input to the following Perl script (the\
   output should be redirected to a file or piped to "tar -xzvf -").\
\
\
\
\
\
\
\
\
\
\
\
Peterson & Jennings         Standards Track                    [Page 34]\
\
RFC 4474                      SIP Identity                   August 2006\
\
\
   #!/usr/bin/perl\
   use strict;\
   my $bdata = "";\
   use MIME::Base64;\
   while(<>) {\
    if (/-- BEGIN MESSAGE ARCHIVE --/ .. /-- END MESSAGE ARCHIVE --/) {\
        if ( m/^\\s*[^\\s]+\\s*$/) {\
            $bdata = $bdata . $_;\
        }\
     }\
   }\
   print decode_base64($bdata);\
\
   Alternatively, the base-64 encoded block can be edited by hand to\
   remove document structure lines and fed as input to any base-64\
   decoding utility.\
\
B.1.  Encoded Reference Files\
\
   -- BEGIN MESSAGE ARCHIVE --\
   H4sICFfaz0QCA25ld2lkZW50LnRhcgDsW0us5NhZ7gUSwqiF2CAhFikiIQhFt992\
   +U46it+u8qPK5Uc9WPlVfj/KdpXtomEDCxaAhFggISE2WSHCIoIFioQQC8gqAhRA\
   QQTY8JJAbMgGIYTv7b7T09PT0xNl+mqS3F8qVd3jY/uc85//+87/nXOLoIv9oGjB\
   B2/PIAiDSBwfv1GERInxG8EwAh6/37UHMIQRKIljCI4+gGCUGKtP8Ad3YKemderJ\
   5EFSBW1QN2Xxmnp5GtblqXqUPfIffBdZcet/p82conUee0H9sfsfhiACw17nfwQa\
   y+Dra+MkQGFkrI+TOPJgAt37/63bo2tjeHGuTVh+bc6FOUub/E0poM7nLGqyLJ06\
   Id3NGTocPxytMWF6jNJYpDqIoXVLoDlmr+pNx+o7ztZ1ke8WtnXhFUClU5GGLZ6l\
   O3YN8T3P0Usm1GyG9lQGEiBXFE6+yPecSSvPykuV4TPB5ne9xNEO8KxQVXnk3cqn\
   /TaK3C3T7A08cRGokyJPUzmrV7k5pHK7i5bQyOambNcDLxUmH9zMD2sl8FGa+WGt\
   BG6bGe5nHafvFnK5n0dnT6N1nmF0mgt3EK3OxQVdiuMzZrNOhPxNOF37W7w4LmsL\
   OA0Mpeqt7RTKTrDX1CztZgezbM7rLlvQeBnhWzWOV5qDZEdMahLZTo8Wq0oZOL4X\
   FgkgMhY4pNBdU53sHVvlaIX5TjqH0+JkYXAXmmzgSI7H9N3RvHingrIOAUIzCph4\
   GhsdHGDwET+WCO5SuDtwxXKNvneGYrWiQ5WhaTEJXb0LXb6Trgd2DS0ZZscLWm6B\
   au3aO48HZK4GEWgzN2oRTuBaG/vLXA+aZKh8kDBYyJj7bHWREXgjMWxIgFQrxPyx\
   b3eUc3EEH6iEptuYL1zFRCpr22rPXujFs9EPx0s+o67pbhzRa/eOjvEZX+wjt1hH\
   gKpDHdvdXJA5er1Y22tRXXed+KwyxzFadFtZyW1st4E7V7ROO4Rqw5Cnx6ncXb/Z\
   5ztdUOmx34dX3Ck8cydPc76+a5uO4XLTMI9Q3iIwDJBOloNbUahd5OK7FnQu637t\
   L/cQdlSHel5tRVjh84Jfhl7pDfV2zZyPeEVs3D3t8XoKAVzDo3YAad6sp4r8nCUb\
   UmxUUWAL9lRiS848gHAm+nZNcQF78RIY2lk6qq6DnFO30Q4B2JaLG2WTkcZ2uVx7\
   ezqGS4vqngA30c5r3KsI8ODevsvtFf6v6vicBsMd8j+ME+Qt/0PjAnCsT5AQes//\
   d8z/a4OerNZze4z+iczvXqwBtvrI+7TMhDq3WqlMK9nlKt3a0z2RHGGlCQ8jMtub\
   akAY2zocFupKgghFgbyFoS8BZx7Yl3mZXDZt5ZwYcj5kezmjEwY/YCO4rk+lFQc+\
   26mK7GYb+rhviUDaVKy2X5DZUvOAOd8VeYQUtOfJ6QxVKtCW0DakDRBDOb3cIk3h\
   F7toGs5wBFldupDkxU1TXS7dnKN1mgFumFWGNmhb8AJH0omt08VC23Jtj1O0A9sn\
   ZMFvA6KMp8s6FYZmkbj7RdcoudzWYdsCq+3SmrVIvq9iqJOxaIu1+6ho406UU2vF\
   ohHFJNVUDOr4sEIxeK0O6nJKHFZhclxeLK4DpvUqSdSqG1+eerx35ELXrPfF5gzq\
   BWs4joD2qSUehFTp8aXsremUp0mrLxp+tnVMFALaFWhZHg6HWorIohz2um5KZcV4\
   QUcNh4BdC9HZV8ikckSn5WM83neiONKavbQlS4MlANoplaQn67JbMLQ2XSPumQa1\
\
\
\
Peterson & Jennings         Standards Track                    [Page 35]\
\
RFC 4474                      SIP Identity                   August 2006\
\
\
   OD9iBLYPiyDjudXR4en9xuHQdHmIDGp6VsjyyBvTE85DwIJMty65T2PDtkJqa4Gz\
   Va/KPcjRF8i38qUytVhdmrEUb1rqHDnx7lFyGd+2RC1FCYwFOMErfKO3oymKyceF\
   n8Q7oyfs1eqMEFsqJw1oOfhmaoQNCmJluerLmeSox20+g1idmdZA7zKolVXLMvKY\
   TpCp3KwzlSHYhjpmBCGHXZEp1CnlI0nalZdxHPxtUDLsEFlNGfqGBRCgY9CCd97w\
   YpuQ4HlY8Kyus6wBZ3LIb0tNXx2XmpOdd9EwqPv1VlB8Dgvdbr2S4dNWBnZVirLp\
   Qbgsh0MSKJ646reXI3K8nKSLaHL9nlrRQdVtsbWRviDVDwyrTzD+n9yPGf7fhP8j\
   5kO3+I/AN/k/gZHYPf7fMf6vLEaZs++FfvGg0pDIGkfRmLsj2PLX6R5NY6JGcywT\
   6x9OCcDrOOGjUgLwOk74qJQAvJYT3o3O93f6e3b958ZZ2cdvQ/55s/6DvEf/QbBr\
   /YeAifv4/yToP3DCsnQyfZP+s32j/mOO6Tp3ub75uf6TLipXpDDH5DWVbp7VCzve\
   sGxrnfDuWEEErgvprjN2eda4aFS9PzVXGWzLmTSsmvSgcTQyfgYtK6/LkOsy4D2F\
   nX15k4AAm6p+k9Y/FxD2LOBs+nMgph+o/YgXev+u9pM/746BZ4EotJ7YZ0qunQHX\
   ZJni8v5B4wWaXjKJTnfhLmWvRYMzIXYbFjI5jFzInZwlZZR0gmoAGoi39e6ENYEk\
   HsO0UyJ7umXRkl/i+LGOLxE6zD3bkFOqoJYZrS3Mo5bYjjSc16cLjwvABjZ3Tbgw\
   EIHu51MYjruBLihkPUwjBwTDKJjJ0MqZLpQpjMVG40i2HhaHDtNTcH08ZDpASGdm\
   Vh2T7DzUC/SINbE6epSnaWfJNGP36oT2b+QcHeOFULeg/XStYOQGpFdc6+EMcDBK\
   fXviBR7sukN3IxIljBR2fkm/UvlF3SHaEOu9Kng98MJNO5PObPM9s20E9IU2zrbV\
   NVXduLbrRP35fLmVfYCXdZ9mrHGr+yzi5y5+n7CIsCNRdBx901oTYGirG/vMgJcP\
   mP/XeqHOxIMszduZuT2I2qEqFtsYT9j4suzz3WwHhFkxa4eV4ATDkcJN0Tub7Obi\
   l4xiVww3PVTrTb0F53O84Qlbcl16TBnsXHb33UWn26oCVojgnBJk1lLYPuAkDTkf\
   L8mhkBJ2iWCpiC5OB8ScQXFWUTvJ47o+sYS6nRFWkbHTIfaBwTGDU7PBxRN5hsMn\
   97rPvb3K/29B/nmz/kOit/wPI+NaYFz/49j9/s8nR/8Jb/UfFixdZqes1VXSpDV9\
   3CxjcUVb/RwFc6SNybjHPOfImvRJ2OKeEoQ6QBb58aQspcM86u350UQOEGHRULYs\
   Ec0uDzIlkqqZ2q6txQOdKTuL4xNyu1G4OXtA95ICEEINTlmB7GqdqrH0TG7jhdyX\
   vs2yPshFrEmJ1dTmymAmDflxuQHlpgjqeJi/pP8syEMjzOWtnCabMJmljbhsIwM1\
   CpjqVwY78D7TH/gcWSUkqF0uQRaDK2/pxB6UAouR+r3iqCEHiQ/mogxSvcX05ukQ\
   6jt7cTwPEr9uiHq7BWMT2xU51cIUhPOxTu0rqannADguEKwdDeu1GNJz6bxXbOVy\
   nFKywvH7qaS7J1ZZbIUp4WYQ7+LMtf5DoESp0loF6Q4K5LsNryOnNhebXZ9ujcPA\
   uPDMZJcd2w5Q4TNrBLsMy4WAaO7eoGbKZSo6CB4d5mIHLiQZKDjKXfKzmXWj/zBr\
   o/IxNzemOTZbgzDarnmDbqXj4GtxsYVSA1xHnVSTeSqZFpqCKiD0etuj2BwV5Yuz\
   79UCoglCNqgzaEh+IUyD1Y2YIgak3kTDfnaKW2XV7jkvYzcRL0vAkdal3OL3Z0tA\
   bEmp3VOqKMtQsmpJcxDMmytnzEcHh7WtoB1yzTsNZhfJCYJ1Ap3SS+ACJj3MV5mG\
   Rp0y1Zos25ebOT47nU8kSB8RD/UuR8cWGddFYbKR2F0op5BLi2jaLdE8BigUVLYb\
   E/b8eGdXOeNJ3M1I51WYCsm035/wcEMbO/yUnKcCq66gTedIeGQW29O0lQNgtUB9\
   ZL7Yy71YZETcymuNFIN1RK0MGUr3Y5osBHZ9bhaYVlYvEewnVwN6Bf8/fvnnW9N/\
   yBv9B8Wge/z/jtB/Xk8JwOs44aNSAvA6TviolAC8lhPu9Z9X4n8IHntOURax52R3\
   G//jAvD5+S8MxbGb9R8K38f/nVgTV1du6X7+OfwHvZNXWfC4rMOn15ecLPaCz9/u\
   Ddxe9cr8qTPDXMwjiYAgRtx+iqDwhNnxT83o9DMTBJ4IgTtBRkdPYOwKpq5weCKq\
   5tOn9wnXJzn+b37F7cdM/2/M/2AUe3H+E7vZ/0eg+/2fO7ExZicvAr3yUPTxB0T7\
   xJivQOQx9BCwY+fq9i/QVIwJTI2/HiOPsXfc2im86MmFikTMlQunifwGHm9Rnf6R\
   UNadU/vN1YQcS4S6zK8mTOlOPvt6/PncO60TPnEIb4Z7h4eAWV5N6OtGPrvntcD0\
   7LaxVTMUgkkSewhwThtcTT4UmB4CrJNlj+bc1eRlXBsvGMHxavIc3h4C8+chcjX5\
   dHPGWbOEcPlYGXkrtajv8fEShNmNaezbQkRjewoX+alWtjYo5e2gGaTS1iHlZ326\
   uZQPgckLCyzSJ5f2TOoC0+RK10bj1szDVccKicPn6sDPUZ80Bg2BB40rEX4NLs9h\
   20HKCfeaefXSw6rVcRnCp23hXyRXJPM1sc4oprAi6XSw126Fw2qBdlB4sJonn37R\
   p0fz4jCO8mejtq2aKxB81Sfv2SX63DtOFj6pG+dREznwOE5l0Y6PeaQERdhGV5Nx\
   6O7R9TsM//OgaZwwuOP9Pwh7cf57hH7i5vw3gd/j/z3+fyz4/1Gh/XsSwV6K/2sk\
   fwvveFP8QyRxm/9hY43r+Efg+/Ofd2KGRMM/9VLu/5knkwM5IyjUP6A4jPuI5wfU\
   GEw4jsEocX2ghnQdGMbgA3bP8N9l8R+HReDfefwj7/7/H0ZCOPHs/A95H/93YV/6\
\
\
\
Peterson & Jennings         Standards Track                    [Page 36]\
\
RFC 4474                      SIP Identity                   August 2006\
\
\
   P0b7Veqnf3f9W3/5n9/42+/75f/65g/4f3X4+p/9w0/8wt8Mv/97f/jX/zt88Stf\
   +/Ljv/unb379+OvZvw3aN/7jn59+6vt/Q7n6sU3/RS36oT/5cS+a/8pXGLL7gy+R\
   eY1dET/8qa/+8Q9Wf/HlP6r/9DNf+J9f+8Wf/c3f/vs/z4p/Eb8Q/PePfu2Xfu53\
   rB/59381fvIfH05+Xr6PwE9c/D8OCu9u4/+F/nt9BOBG/yXuz//djf77bYoYwLcr\
   XADfilhxv+B4a/EfF+e4fTtbQG+Kfxy6Pv+D4SiMosTN+V9yzAnu4/9O4v9DN3k+\
   ZHfoffs/6JgQ4NRkrtlz84N2gdArCLmC0JtdoDfrDU/PT8bsu3xiNUFN/3875/Pa\
   NBiH8Yt6CBS0Q2SDYcYEkSl9k75Nmkmn7ebWde2WLm3646Jp2q7FtU2btq496EGc\
   KMgu4sH5a4dN8NccCMLYP6AMwcv+Bg/e1NMuZimTdlvXyWxx4/s5pQ0N5SXPk/d9\
   nrclaSuHrBhbaKb6cHiUHOYxWe8SBkK1CTFVTWbSpDDAGwjZ1vATeRvaWPWnbFIh\
   msyQmKNYmhz38Sa7yG+ckGy5vJKSlF5E8v0ev8mq3bwHPCTYqv9mVEAN9//p+Z+m\
   f9qCMMvqv/+k4fnfEiqCJbcJfVPnuyR/9XS0YxBorSR4jTK/zWywKUlfjUftlEvW\
   a4qqzKsSE0pyvrf629Ubir6awigcGnVEnP0IiZ5wjr4ezjNiqr/IZ9IBl2eo6PU5\
   BrITiUwg5p5yxcsOWqKUKXvOLE7kHEhQBbtU0/Ek4+p4NDnGZ7zh0FiJvpETJxKF\
   hKx6Is6AXxicGmYUJmvxjXmDTk+qzBSuZMxq0aUKTszlE6WhdM3FBkU5XZLCPT2l\
   8UlHKOT1ubOBsqtnREzwI5G436TkSgkxzYVkxr9bYbTDCFT/r0y9yshXUrRhlxRF\
   G0sprxm2SY0q2/NYCrMGwkDAo6GZ/t+MCqhh/4/MVf2Pvv7DDMz/wP8Pg/+DyQEH\
   yP+bUQE23P+JqD/zfxpZ9P5fewv8vwXo/d/W7OecjaRZhGWaZq04LtGUjCPIwkUQ\
   krUXmI1xEstIUQmbOVD/IdN/EyrAPfZ/Ff2z+v5P7RD03wpit+2TyoevQvtisv3j\
   fJz48e1pxN3xs+1I74vpO89MxqurnY/XnlxeLFx702lcIjvurZ8ods/MHQtevPD+\
   bbBr+dR5amnN25XtflV+/fCLPbs62/fO+OD7yqzx9EzqbtfLk4GznxZurp+JHZ0+\
   7l5+tPr8vtj2OfXr0sLKnHgrqM6DAv9H/f/bCnCP/Z+ufzOm9PyfhfVfS9hvJkXs\
   N4ci/iZ7gtkGAAAAAAAAAAAAAAAAAAAAAAAAAABAPX4DY+BfEQB4AAA=\
   -- END MESSAGE ARCHIVE --\
\
\
\
\
\
\
\
\
\
\
\
\
\
\
\
\
\
\
\
\
\
\
\
\
\
\
\
\
Peterson & Jennings         Standards Track                    [Page 37]\
\
RFC 4474                      SIP Identity                   August 2006\
\
\
Appendix C.  Original Requirements\
\
   The following requirements were crafted throughout the development of\
   the mechanism described in this document.  They are preserved here\
   for historical reasons.\
\
   o  The mechanism must allow a UAC or a proxy server to provide a\
      strong cryptographic identity assurance in a request that can be\
      verified by a proxy server or UAS.\
   o  User agents that receive identity assurances must be able to\
      validate these assurances without performing any network lookup.\
   o  User agents that hold certificates on behalf of their user must be\
      capable of adding this identity assurance to requests.\
   o  Proxy servers that hold certificates on behalf of their domain\
      must be capable of adding this identity assurance to requests; a\
      UAC is not required to support this mechanism in order for an\
      identity assurance to be added to a request in this fashion.\
   o  The mechanism must prevent replay of the identity assurance by an\
      attacker.\
   o  In order to provide full replay protection, the mechanism must be\
      capable of protecting the integrity of SIP message bodies (to\
      ensure that media offers and answers are linked to the signaling\
      identity).\
   o  It must be possible for a user to have multiple AoRs (i.e.,\
      accounts or aliases) that it is authorized to use within a\
      domain, and for the UAC to assert one identity while\
      authenticating itself as another, related, identity, as permitted\
      by the local policy of the domain.\
\
\
\
\
\
\
\
\
\
\
\
\
\
\
\
\
\
\
\
\
\
\
\
Peterson & Jennings         Standards Track                    [Page 38]\
\
RFC 4474                      SIP Identity                   August 2006\
\
\
References\
\
Normative References\
\
   [1]   Rosenberg, J., Schulzrinne, H., Camarillo, G., Johnston, A.,\
         Peterson, J., Sparks, R., Handley, M., and E. Schooler, "SIP:\
         Session Initiation Protocol", RFC 3261, June 2002.\
\
   [2]   Bradner, S., "Key words for use in RFCs to Indicate Requirement\
         Levels", BCP 14, RFC 2119, March 1997.\
\
   [3]   Peterson, J., "A Privacy Mechanism for the Session Initiation\
         Protocol (SIP)", RFC 3323, November 2002.\
\
   [4]   Rosenberg, J. and H. Schulzrinne, "Session Initiation Protocol\
         (SIP): Locating SIP Servers", RFC 3263, June 2002.\
\
   [5]   Peterson, J., "Session Initiation Protocol (SIP) Authenticated\
         Identity Body (AIB) Format", RFC 3893, September 2004.\
\
   [6]   Crocker, D. and P. Overell, "Augmented BNF for Syntax\
         Specifications: ABNF", RFC 4234, October 2005.\
\
   [7]   Housley, R., "Cryptographic Message Syntax (CMS) Algorithms",\
         RFC 3370, August 2002.\
\
   [8]   Josefsson, S., "The Base16, Base32, and Base64 Data Encodings",\
         RFC 3548, July 2003.\
\
   [9]   Housley, R., Polk, W., Ford, W., and D. Solo, "Internet X.509\
         Public Key Infrastructure Certificate and Certificate\
         Revocation List (CRL) Profile", RFC 3280, April 2002.\
\
   [10]  Housley, R. and P. Hoffman, "Internet X.509 Public Key\
         Infrastructure Operational Protocols: FTP and HTTP", RFC 2585,\
         May 1999.\
\
   [11]  Rescorla, E., "HTTP Over TLS", RFC 2818, May 2000.\
\
Informative References\
\
   [12]  Jennings, C., Peterson, J., and M. Watson, "Private Extensions\
         to the Session Initiation Protocol (SIP) for Asserted Identity\
         within Trusted Networks", RFC 3325, November 2002.\
\
   [13]  Schulzrinne, H., "The tel URI for Telephone Numbers", RFC 3966,\
         December 2004.\
\
\
\
\
Peterson & Jennings         Standards Track                    [Page 39]\
\
RFC 4474                      SIP Identity                   August 2006\
\
\
   [14]  Faltstrom, P. and M. Mealling, "The E.164 to Uniform Resource\
         Identifiers (URI) Dynamic Delegation Discovery System (DDDS)\
         Application (ENUM)", RFC 3761, April 2004.\
\
   [15]  Peterson, J., "Retargeting and Security in SIP: A Framework and\
         Requirements", Work in Progress, February 2005.\
\
   [16]  Sparks, R., Ed., Hawrylyshen, A., Johnston, A., Rosenberg, J.,\
         and H. Schulzrinne, "Session Initiation Protocol (SIP) Torture\
         Test Messages, RFC 4475, May 2006.\
\
Authors' Addresses\
\
   Jon Peterson\
   NeuStar, Inc.\
   1800 Sutter St\
   Suite 570\
   Concord, CA  94520\
   US\
\
   Phone: +1 925/363-8720\
   EMail: jon.peterson@neustar.biz\
   URI:   http://www.neustar.biz/\
\
\
   Cullen Jennings\
   Cisco Systems\
   170 West Tasman Drive\
   MS: SJC-21/2\
   San Jose, CA  95134\
   USA\
\
   Phone: +1 408 902-3341\
   EMail: fluffy@cisco.com\
\
\
\
\
\
\
\
\
\
\
\
\
\
\
\
\
\
Peterson & Jennings         Standards Track                    [Page 40]\
\
RFC 4474                      SIP Identity                   August 2006\
\
\
Full Copyright Statement\
\
   Copyright (C) The Internet Society (2006).\
\
   This document is subject to the rights, licenses and restrictions\
   contained in BCP 78, and except as set forth therein, the authors\
   retain all their rights.\
\
   This document and the information contained herein are provided on an\
   "AS IS" basis and THE CONTRIBUTOR, THE ORGANIZATION HE/SHE REPRESENTS\
   OR IS SPONSORED BY (IF ANY), THE INTERNET SOCIETY AND THE INTERNET\
   ENGINEERING TASK FORCE DISCLAIM ALL WARRANTIES, EXPRESS OR IMPLIED,\
   INCLUDING BUT NOT LIMITED TO ANY WARRANTY THAT THE USE OF THE\
   INFORMATION HEREIN WILL NOT INFRINGE ANY RIGHTS OR ANY IMPLIED\
   WARRANTIES OF MERCHANTABILITY OR FITNESS FOR A PARTICULAR PURPOSE.\
\
Intellectual Property\
\
   The IETF takes no position regarding the validity or scope of any\
   Intellectual Property Rights or other rights that might be claimed to\
   pertain to the implementation or use of the technology described in\
   this document or the extent to which any license under such rights\
   might or might not be available; nor does it represent that it has\
   made any independent effort to identify any such rights.  Information\
   on the procedures with respect to rights in RFC documents can be\
   found in BCP 78 and BCP 79.\
\
   Copies of IPR disclosures made to the IETF Secretariat and any\
   assurances of licenses to be made available, or the result of an\
   attempt made to obtain a general license or permission for the use of\
   such proprietary rights by implementers or users of this\
   specification can be obtained from the IETF on-line IPR repository at\
   http://www.ietf.org/ipr.\
\
   The IETF invites any interested party to bring to its attention any\
   copyrights, patents or patent applications, or other proprietary\
   rights that may cover technology that may be required to implement\
   this standard.  Please address the information to the IETF at\
   ietf-ipr@ietf.org.\
\
Acknowledgement\
\
   Funding for the RFC Editor function is provided by the IETF\
   Administrative Support Activity (IASA).\
\
\
\
\
\
\
\
Peterson & Jennings         Standards Track                    [Page 41]\
\

doc 11
  field 0
    name titolo
    type string
    value rfc4475.txt
  field 1
    name contenuto
    type string
    value \
\
\
\
\
\
Network Working Group                                     R. Sparks, Ed.\
Request for Comments: 4475                              Estacado Systems\
Category: Informational                                   A. Hawrylyshen\
                                                         Ditech Networks\
                                                             A. Johnston\
                                                                   Avaya\
                                                            J. Rosenberg\
                                                           Cisco Systems\
                                                          H. Schulzrinne\
                                                     Columbia University\
                                                                May 2006\
\
\
        Session Initiation Protocol (SIP) Torture Test Messages\
\
Status of This Memo\
\
   This memo provides information for the Internet community.  It does\
   not specify an Internet standard of any kind.  Distribution of this\
   memo is unlimited.\
\
Copyright Notice\
\
   Copyright (C) The Internet Society (2006).\
\
Abstract\
\
   This informational document gives examples of Session Initiation\
   Protocol (SIP) test messages designed to exercise and "torture" a SIP\
   implementation.\
\
Table of Contents\
\
   1. Overview ........................................................3\
   2. Document Conventions ............................................3\
      2.1. Representing Long Lines ....................................4\
      2.2. Representing Non-printable Characters ......................4\
      2.3. Representing Long Repeating Strings ........................5\
   3. SIP Test Messages ...............................................5\
      3.1. Parser Tests (syntax) ......................................5\
           3.1.1. Valid Messages ......................................5\
                  3.1.1.1. A Short Tortuous INVITE ....................5\
                  3.1.1.2. Wide Range of Valid Characters .............8\
                  3.1.1.3. Valid Use of the % Escaping Mechanism ......9\
                  3.1.1.4. Escaped Nulls in URIs .....................11\
                  3.1.1.5. Use of % When It Is Not an Escape .........11\
                  3.1.1.6. Message with No LWS between\
                           Display Name and < ........................12\
\
\
\
Sparks, et al.               Informational                      [Page 1]\
\
RFC 4475               SIP Torture Test Messages                May 2006\
\
\
                  3.1.1.7. Long Values in Header Fields ..............12\
                  3.1.1.8. Extra Trailing Octets in a UDP Datagram ...14\
                  3.1.1.9. Semicolon-Separated Parameters in\
                           URI User Part .............................16\
                  3.1.1.10. Varied and Unknown Transport Types .......16\
                  3.1.1.11. Multipart MIME Message ...................17\
                  3.1.1.12. Unusual Reason Phrase ....................18\
                  3.1.1.13. Empty Reason Phrase ......................19\
           3.1.2. Invalid Messages ...................................20\
                  3.1.2.1. Extraneous Header Field Separators ........20\
                  3.1.2.2. Content Length Larger Than Message ........20\
                  3.1.2.3. Negative Content-Length ...................21\
                  3.1.2.4. Request Scalar Fields with\
                           Overlarge Values ..........................22\
                  3.1.2.5. Response Scalar Fields with\
                           Overlarge Values ..........................23\
                  3.1.2.6. Unterminated Quoted String in\
                           Display Name ..............................24\
                  3.1.2.7. <> Enclosing Request-URI ..................25\
                  3.1.2.8. Malformed SIP Request-URI (embedded LWS) ..26\
                  3.1.2.9. Multiple SP Separating\
                           Request-Line Elements .....................27\
                  3.1.2.10. SP Characters at End of Request-Line .....28\
                  3.1.2.11. Escaped Headers in SIP Request-URI .......29\
                  3.1.2.12. Invalid Timezone in Date Header Field ....30\
                  3.1.2.13. Failure to Enclose name-addr URI in <> ...31\
                  3.1.2.14. Spaces within addr-spec ..................31\
                  3.1.2.15. Non-token Characters in Display Name .....32\
                  3.1.2.16. Unknown Protocol Version .................32\
                  3.1.2.17. Start Line and CSeq Method Mismatch ......33\
                  3.1.2.18. Unknown Method with CSeq Method Mismatch .33\
                  3.1.2.19. Overlarge Response Code ..................34\
      3.2. Transaction Layer Semantics ...............................34\
           3.2.1. Missing Transaction Identifier .....................34\
      3.3. Application-Layer Semantics ...............................35\
           3.3.1. Missing Required Header Fields .....................35\
           3.3.2. Request-URI with Unknown Scheme ....................36\
           3.3.3. Request-URI with Known but Atypical Scheme .........36\
           3.3.4. Unknown URI Schemes in Header Fields ...............37\
           3.3.5. Proxy-Require and Require ..........................37\
           3.3.6. Unknown Content-Type ...............................38\
           3.3.7. Unknown Authorization Scheme .......................38\
           3.3.8. Multiple Values in Single Value Required Fields ....39\
           3.3.9. Multiple Content-Length Values .....................40\
           3.3.10. 200 OK Response with Broadcast Via Header\
                   Field Value .......................................40\
           3.3.11. Max-Forwards of Zero ..............................41\
           3.3.12. REGISTER with a Contact Header Parameter ..........42\
\
\
\
Sparks, et al.               Informational                      [Page 2]\
\
RFC 4475               SIP Torture Test Messages                May 2006\
\
\
           3.3.13. REGISTER with a url-parameter .....................42\
           3.3.14. REGISTER with a URL Escaped Header ................43\
           3.3.15. Unacceptable Accept Offering ......................44\
      3.4. Backward Compatibility ....................................44\
           3.4.1. INVITE with RFC 2543 Syntax ........................44\
   4. Security Considerations ........................................45\
   5. Acknowledgements ...............................................46\
   6. Informative References .........................................46\
   Appendix A. Bit-Exact Archive of Each Test Message ................47\
      A.1. Encoded Reference Messages ................................48\
\
1.  Overview\
\
   This document is informational and is NOT NORMATIVE on any aspect of\
   SIP.\
\
   This document contains test messages based on the current version\
   (2.0) of the Session Initiation Protocol as, defined in [RFC3261].\
   Some messages exercise SIP's use of the Session Description Protocol\
   (SDP), as described in [RFC3264].\
\
   These messages were developed and refined at the SIPIt\
   interoperability test events.\
\
   The test messages are organized into several sections.  Some stress\
   only a SIP parser, and others stress both the parser and the\
   application above it.  Some messages are valid, and some are not.\
   Each example clearly calls out what makes any invalid messages\
   incorrect.\
\
   This document does not attempt to catalog every way to make an\
   invalid message, nor does it attempt to be comprehensive in exploring\
   unusual, but valid, messages.  Instead, it tries to focus on areas\
   that have caused interoperability problems or that have particularly\
   unfavorable characteristics if they are handled improperly.  This\
   document is a seed for a test plan, not a test plan in itself.\
\
   The messages are presented in the text using a set of markup\
   conventions to avoid ambiguity and meet Internet-Draft layout\
   requirements.  To resolve any remaining ambiguity, a bit-accurate\
   version of each message is encapsulated in an appendix.\
\
2.  Document Conventions\
\
   This document contains many example SIP messages.  Although SIP is a\
   text-based protocol, many of these examples cannot be unambiguously\
   rendered without additional markup due to the constraints placed on\
   the formatting of RFCs.  This document defines and uses the markup\
\
\
\
Sparks, et al.               Informational                      [Page 3]\
\
RFC 4475               SIP Torture Test Messages                May 2006\
\
\
   defined in this section to remove that ambiguity.  This markup uses\
   the start and end tag conventions of XML but does not define any XML\
   document type.\
\
   The appendix contains an encoded binary form of all the messages and\
   the algorithm needed to decode them into files.\
\
2.1.  Representing Long Lines\
\
   Several of these examples contain unfolded lines longer than 72\
   characters.  These are captured between <allOneLine/> tags.  The\
   single unfolded line is reconstructed by directly concatenating all\
   lines appearing between the tags (discarding any line feeds or\
   carriage returns).  There will be no whitespace at the end of lines.\
   Any whitespace appearing at a fold-point will appear at the beginning\
   of a line.\
\
   The following represent the same string of bits:\
\
      Header-name: first value, reallylongsecondvalue, third value\
\
      <allOneLine>\
      Header-name: first value,\
       reallylongsecondvalue\
      , third value\
      </allOneLine>\
\
      <allOneLine>\
      Header-name: first value,\
       reallylong\
      second\
      value,\
       third value\
      </allOneLine>\
\
   Note that this is NOT SIP header-line folding, where different\
   strings of bits have equivalent meaning.\
\
2.2.  Representing Non-printable Characters\
\
   Several examples contain binary message bodies or header field values\
   containing non-ascii range UTF-8 encoded characters.  These are\
   rendered here as a pair of hexadecimal digits per octet between\
   <hex/> tags.  This rendering applies even inside quoted-strings.\
\
\
\
\
\
\
\
Sparks, et al.               Informational                      [Page 4]\
\
RFC 4475               SIP Torture Test Messages                May 2006\
\
\
   The following represent the same string of bits:\
\
      Header-name: value one\
      Header-name: value<hex>206F6E</hex>e\
\
   The following is a Subject header field containing the euro symbol:\
\
      Subject: <hex>E282AC</hex>\
\
2.3.  Representing Long Repeating Strings\
\
   Several examples contain very large data values created with\
   repeating bit strings.  Those will be rendered here using <repeat\
   count=some_integer>value</repeat>.  As with <hex>, this rendering\
   applies even inside quoted strings.\
\
   For example, the value "abcabcabc" can be rendered as <repeat\
   count=3>abc</repeat>.  A display name of "1000000 bottles of beer"\
   could be rendered as\
\
      To: "1<repeat count=6><hex>30</hex></repeat> bottles of beer"\
          <sip:beer.example.com>\
\
   A Max-Forwards header field with a value of one google will be\
   rendered here as\
\
      Max-Forwards: 1<repeat count=100>0</repeat>\
\
3.  SIP Test Messages\
\
3.1.  Parser Tests (syntax)\
\
3.1.1.  Valid Messages\
\
3.1.1.1.  A Short Tortuous INVITE\
\
   This short, relatively human-readable message contains:\
\
   o  line folding all over.\
\
   o  escaped characters within quotes.\
\
   o  an empty subject.\
\
   o  LWS between colons, semicolons, header field values, and other\
      fields.\
\
   o  both comma separated and separately listed header field values.\
\
\
\
Sparks, et al.               Informational                      [Page 5]\
\
RFC 4475               SIP Torture Test Messages                May 2006\
\
\
   o  a mix of short and long form for the same header field name.\
\
   o  unknown Request-URI parameter.\
\
   o  unknown header fields.\
\
   o  an unknown header field with a value that would be syntactically\
      invalid if it were defined in terms of generic-param.\
\
   o  unusual header field ordering.\
\
   o  unusual header field name character case.\
\
   o  unknown parameters of a known header field.\
\
   o  a uri parameter with no value.\
\
   o  a header parameter with no value.\
\
   o  integer fields (Max-Forwards and CSeq) with leading zeros.\
\
   All elements should treat this as a well-formed request.\
\
   The UnknownHeaderWithUnusualValue header field deserves special\
   attention.  If this header field were defined in terms of comma-\
   separated values with semicolon-separated parameters (as would many\
   of the existing defined header fields), this would be invalid.\
   However, since the receiving element does not know the definition of\
   the syntax for this field, it must parse it as a header value.\
   Proxies would forward this header field unchanged.  Endpoints would\
   ignore the header field.\
\
\
\
\
\
\
\
\
\
\
\
\
\
\
\
\
\
\
\
\
Sparks, et al.               Informational                      [Page 6]\
\
RFC 4475               SIP Torture Test Messages                May 2006\
\
\
      Message Details : wsinv\
\
      INVITE sip:vivekg@chair-dnrc.example.com;unknownparam SIP/2.0\
      TO :\
       sip:vivekg@chair-dnrc.example.com ;   tag    = 1918181833n\
      from   : "J Rosenberg \\\\\\""       <sip:jdrosen@example.com>\
        ;\
        tag = 98asjd8\
      MaX-fOrWaRdS: 0068\
      Call-ID: wsinv.ndaksdj@192.0.2.1\
      Content-Length   : 150\
      cseq: 0009\
        INVITE\
      Via  : SIP  /   2.0\
       /UDP\
          192.0.2.2;branch=390skdjuw\
      s :\
      NewFangledHeader:   newfangled value\
       continued newfangled value\
      UnknownHeaderWithUnusualValue: ;;,,;;,;\
      Content-Type: application/sdp\
      Route:\
       <sip:services.example.com;lr;unknownwith=value;unknown-no-value>\
      v:  SIP  / 2.0  / TCP     spindle.example.com   ;\
        branch  =   z9hG4bK9ikj8  ,\
       SIP  /    2.0   / UDP  192.168.255.111   ; branch=\
       z9hG4bK30239\
      m:"Quoted string \\"\\"" <sip:jdrosen@example.com> ; newparam =\
            newvalue ;\
        secondparam ; q = 0.33\
\
      v=0\
      o=mhandley 29739 7272939 IN IP4 192.0.2.3\
      s=-\
      c=IN IP4 192.0.2.4\
      t=0 0\
      m=audio 49217 RTP/AVP 0 12\
      m=video 3227 RTP/AVP 31\
      a=rtpmap:31 LPC\
\
\
\
\
\
\
\
\
\
\
\
\
Sparks, et al.               Informational                      [Page 7]\
\
RFC 4475               SIP Torture Test Messages                May 2006\
\
\
3.1.1.2.  Wide Range of Valid Characters\
\
   This message exercises a wider range of characters in several key\
   syntactic elements than implementations usually see.  In particular,\
   note the following:\
\
   o  The Method contains non-alpha characters from token.  Note that %\
      is not an escape character for this field.  A method of IN%56ITE\
      is an unknown method.  It is not the same as a method of INVITE.\
\
   o  The Request-URI contains unusual, but legal, characters.\
\
   o  A branch parameter contains all non-alphanum characters from\
      token.\
\
   o  The To header field value's quoted string contains quoted-pair\
      expansions, including a quoted NULL character.\
\
   o  The name part of name-addr in the From header field value contains\
      multiple tokens (instead of a quoted string) with all non-alphanum\
      characters from the token production rule.  That value also has an\
      unknown header parameter whose name contains the non-alphanum\
      token characters and whose value is a non-ascii range UTF-8\
      encoded string.  The tag parameter on this value contains the\
      non-alphanum token characters.\
\
   o  The Call-ID header field value contains the non-alphanum\
      characters from word.  Notice that in this production:\
\
      *  % is not an escape character.  It is only an escape character\
         in productions matching the rule "escaped".\
\
      *  " does not start a quoted string.  None of ',` or " imply that\
         there will be a matching symbol later in the string.\
\
      *  The characters []{}()<> do not have any grouping semantics.\
         They are not required to appear in balanced pairs.\
\
   o  There is an unknown header field (matching extension-header) with\
      non-alphanum token characters in its name and a UTF8-NONASCII\
      value.\
\
   If this unusual URI has been defined at a proxy, the proxy will\
   forward this request normally.  Otherwise, a proxy will generate a\
   404.  Endpoints will generate a 501 listing the methods they\
   understand in an Allow header field.\
\
\
\
\
\
Sparks, et al.               Informational                      [Page 8]\
\
RFC 4475               SIP Torture Test Messages                May 2006\
\
\
      Message Details : intmeth\
\
      <allOneLine>\
      !interesting-Method0123456789_*+`.%indeed'~\
       sip:1_unusual.URI~(to-be!sure)&isn't+it$/crazy?,/;;*\
      :&it+has=1,weird!*pas$wo~d_too.(doesn't-it)\
      @example.com SIP/2.0\
      </allOneLine>\
      Via: SIP/2.0/TCP host1.example.com;branch=z9hG4bK-.!%66*_+`'~\
      <allOneLine>\
      To: "BEL:\\<hex>07</hex> NUL:\\<hex>00</hex> DEL:\\<hex>7F</hex>"\
       <sip:1_unusual.URI~(to-be!sure)&isn't+it$/crazy?,/;;*\
      @example.com>\
      </allOneLine>\
      <allOneLine>\
      From: token1~` token2'+_ token3*%!.- <sip:mundane@example.com>\
      ;fromParam''~+*_!.-%=\
      "<hex>D180D0B0D0B1D0BED182D0B0D18ED189D0B8D0B9</hex>"\
      ;tag=_token~1'+`*%!-.\
      </allOneLine>\
      Call-ID: intmeth.word%ZK-!.*_+'@word`~)(><:\\/"][?}{\
      CSeq: 139122385 !interesting-Method0123456789_*+`.%indeed'~\
      Max-Forwards: 255\
      <allOneLine>\
      extensionHeader-!.%*+_`'~:\
      <hex>EFBBBFE5A4A7E5819CE99BBB</hex>\
      </allOneLine>\
      Content-Length: 0\
\
3.1.1.3.  Valid Use of the % Escaping Mechanism\
\
   This INVITE exercises the % HEX HEX escaping mechanism in several\
   places.  The request is syntactically valid.  Interesting features\
   include the following:\
\
   o  The request-URI has sips:user@example.com embedded in its\
      userpart.  What that might mean to example.net is beyond the scope\
      of this document.\
\
   o  The From and To URIs have escaped characters in their userparts.\
\
   o  The Contact URI has escaped characters in the URI parameters.\
      Note that the "name" uri-parameter has a value of "value%41",\
      which is NOT equivalent to "valueA".  Per [RFC3986], unescaping\
      URI components is never performed recursively.\
\
\
\
\
\
\
Sparks, et al.               Informational                      [Page 9]\
\
RFC 4475               SIP Torture Test Messages                May 2006\
\
\
   A parser must accept this as a well-formed message.  The application\
   using the message must treat the % HEX HEX expansions as equivalent\
   to the character being encoded.  The application must not try to\
   interpret % as an escape character in those places where % HEX HEX\
   ("escaped" in the grammar) is not a valid part of the construction.\
   In [RFC3261], "escaped" only occurs in the expansions of SIP-URI,\
   SIPS-URI, and Reason-Phrase.\
\
      Message Details : esc01\
\
      INVITE sip:sips%3Auser%40example.com@example.net SIP/2.0\
      To: sip:%75se%72@example.com\
      From: <sip:I%20have%20spaces@example.net>;tag=938\
      Max-Forwards: 87\
      i: esc01.239409asdfakjkn23onasd0-3234\
      CSeq: 234234 INVITE\
      Via: SIP/2.0/UDP host5.example.net;branch=z9hG4bKkdjuw\
      C: application/sdp\
      Contact:\
        <sip:cal%6Cer@host5.example.net;%6C%72;n%61me=v%61lue%25%34%31>\
      Content-Length: 150\
\
      v=0\
      o=mhandley 29739 7272939 IN IP4 192.0.2.1\
      s=-\
      c=IN IP4 192.0.2.1\
      t=0 0\
      m=audio 49217 RTP/AVP 0 12\
      m=video 3227 RTP/AVP 31\
      a=rtpmap:31 LPC\
\
\
\
\
\
\
\
\
\
\
\
\
\
\
\
\
\
\
\
\
\
Sparks, et al.               Informational                     [Page 10]\
\
RFC 4475               SIP Torture Test Messages                May 2006\
\
\
3.1.1.4.  Escaped Nulls in URIs\
\
   This register request contains several URIs with nulls in the\
   userpart.  The message is well formed - parsers must accept this\
   message.  Implementations must take special care when unescaping the\
   Address-of-Record (AOR) in this request so as to not prematurely\
   shorten the username.  This request registers two distinct contact\
   URIs.\
\
      Message Details : escnull\
\
      REGISTER sip:example.com SIP/2.0\
      To: sip:null-%00-null@example.com\
      From: sip:null-%00-null@example.com;tag=839923423\
      Max-Forwards: 70\
      Call-ID: escnull.39203ndfvkjdasfkq3w4otrq0adsfdfnavd\
      CSeq: 14398234 REGISTER\
      Via: SIP/2.0/UDP host5.example.com;branch=z9hG4bKkdjuw\
      Contact: <sip:%00@host5.example.com>\
      Contact: <sip:%00%00@host5.example.com>\
      L:0\
\
3.1.1.5.  Use of % When It Is Not an Escape\
\
   In most of the places % can appear in a SIP message, it is not an\
   escape character.  This can surprise the unwary implementor.  The\
   following well-formed request has these properties:\
\
   o  The request method is unknown.  It is NOT equivalent to REGISTER.\
\
   o  The display name portion of the To and From header fields is\
      "%Z%45".  Note that this is not the same as %ZE.\
\
   o  This message has two Contact header field values, not three.\
      <sip:alias2@host2.example.com> is a C%6Fntact header field value.\
\
   A parser should accept this message as well formed.  A proxy would\
   forward or reject the message depending on what the Request-URI meant\
   to it.  An endpoint would reject this message with a 501.\
\
\
\
\
\
\
\
\
\
\
\
\
Sparks, et al.               Informational                     [Page 11]\
\
RFC 4475               SIP Torture Test Messages                May 2006\
\
\
      Message Details : esc02\
\
      RE%47IST%45R sip:registrar.example.com SIP/2.0\
      To: "%Z%45" <sip:resource@example.com>\
      From: "%Z%45" <sip:resource@example.com>;tag=f232jadfj23\
      Call-ID: esc02.asdfnqwo34rq23i34jrjasdcnl23nrlknsdf\
      Via: SIP/2.0/TCP host.example.com;branch=z9hG4bK209%fzsnel234\
      CSeq: 29344 RE%47IST%45R\
      Max-Forwards: 70\
      Contact: <sip:alias1@host1.example.com>\
      C%6Fntact: <sip:alias2@host2.example.com>\
      Contact: <sip:alias3@host3.example.com>\
      l: 0\
\
3.1.1.6.  Message with No LWS between Display Name and <\
\
   This OPTIONS request is not valid per the grammar in RFC 3261 since\
   there is no LWS between the token in the display name and < in the\
   From header field value.  This has been identified as a specification\
   bug that will be removed when RFC 3261 is revised.  Elements should\
   accept this request as well formed.\
\
      Message Details : lwsdisp\
\
      OPTIONS sip:user@example.com SIP/2.0\
      To: sip:user@example.com\
      From: caller<sip:caller@example.com>;tag=323\
      Max-Forwards: 70\
      Call-ID: lwsdisp.1234abcd@funky.example.com\
      CSeq: 60 OPTIONS\
      Via: SIP/2.0/UDP funky.example.com;branch=z9hG4bKkdjuw\
      l: 0\
\
3.1.1.7.  Long Values in Header Fields\
\
   This well-formed request contains header fields with many values and\
   values that are very long.  Features include the following:\
\
   o  The To header field has a long display name, and long uri\
      parameter names and values.\
\
   o  The From header field has long header parameter names and values,\
      in particular, a very long tag.\
\
   o  The Call-ID is one long token.\
\
\
\
\
\
\
Sparks, et al.               Informational                     [Page 12]\
\
RFC 4475               SIP Torture Test Messages                May 2006\
\
\
      Message Details : longreq\
\
      INVITE sip:user@example.com SIP/2.0\
      <allOneLine>\
      To: "I have a user name of\
       <repeat count=10>extreme</repeat> proportion"\
      <sip:user@example.com:6000;\
      unknownparam1=very<repeat count=20>long</repeat>value;\
      longparam<repeat count=25>name</repeat>=shortvalue;\
      very<repeat count=25>long</repeat>ParameterNameWithNoValue>\
      </allOneLine>\
      <allOneLine>\
      F: sip:\
      <repeat count=5>amazinglylongcallername</repeat>@example.net\
      ;tag=12<repeat count=50>982</repeat>424\
      ;unknownheaderparam<repeat count=20>name</repeat>=\
      unknowheaderparam<repeat count=15>value</repeat>\
      ;unknownValueless<repeat count=10>paramname</repeat>\
      </allOneLine>\
      Call-ID: longreq.one<repeat count=20>really</repeat>longcallid\
      CSeq: 3882340 INVITE\
      <allOneLine>\
      Unknown-<repeat count=20>Long</repeat>-Name:\
       unknown-<repeat count=20>long</repeat>-value;\
       unknown-<repeat count=20>long</repeat>-parameter-name =\
       unknown-<repeat count=20>long</repeat>-parameter-value\
      </allOneLine>\
      Via: SIP/2.0/TCP sip33.example.com\
      v: SIP/2.0/TCP sip32.example.com\
      V: SIP/2.0/TCP sip31.example.com\
      Via: SIP/2.0/TCP sip30.example.com\
      ViA: SIP/2.0/TCP sip29.example.com\
      VIa: SIP/2.0/TCP sip28.example.com\
      VIA: SIP/2.0/TCP sip27.example.com\
      via: SIP/2.0/TCP sip26.example.com\
      viA: SIP/2.0/TCP sip25.example.com\
      vIa: SIP/2.0/TCP sip24.example.com\
      vIA: SIP/2.0/TCP sip23.example.com\
      V :  SIP/2.0/TCP sip22.example.com\
      v :  SIP/2.0/TCP sip21.example.com\
      V  : SIP/2.0/TCP sip20.example.com\
      v  : SIP/2.0/TCP sip19.example.com\
      Via : SIP/2.0/TCP sip18.example.com\
      Via  : SIP/2.0/TCP sip17.example.com\
      Via: SIP/2.0/TCP sip16.example.com\
      Via: SIP/2.0/TCP sip15.example.com\
      Via: SIP/2.0/TCP sip14.example.com\
      Via: SIP/2.0/TCP sip13.example.com\
\
\
\
Sparks, et al.               Informational                     [Page 13]\
\
RFC 4475               SIP Torture Test Messages                May 2006\
\
\
      Via: SIP/2.0/TCP sip12.example.com\
      Via: SIP/2.0/TCP sip11.example.com\
      Via: SIP/2.0/TCP sip10.example.com\
      Via: SIP/2.0/TCP sip9.example.com\
      Via: SIP/2.0/TCP sip8.example.com\
      Via: SIP/2.0/TCP sip7.example.com\
      Via: SIP/2.0/TCP sip6.example.com\
      Via: SIP/2.0/TCP sip5.example.com\
      Via: SIP/2.0/TCP sip4.example.com\
      Via: SIP/2.0/TCP sip3.example.com\
      Via: SIP/2.0/TCP sip2.example.com\
      Via: SIP/2.0/TCP sip1.example.com\
      <allOneLine>\
      Via: SIP/2.0/TCP\
       host.example.com;received=192.0.2.5;\
      branch=very<repeat count=50>long</repeat>branchvalue\
      </allOneLine>\
      Max-Forwards: 70\
      <allOneLine>\
      Contact: <sip:\
      <repeat count=5>amazinglylongcallername</repeat>\
      @host5.example.net>\
      </allOneLine>\
      Content-Type: application/sdp\
      l: 150\
\
      v=0\
      o=mhandley 29739 7272939 IN IP4 192.0.2.1\
      s=-\
      c=IN IP4 192.0.2.1\
      t=0 0\
      m=audio 49217 RTP/AVP 0 12\
      m=video 3227 RTP/AVP 31\
      a=rtpmap:31 LPC\
\
3.1.1.8.  Extra Trailing Octets in a UDP Datagram\
\
   This message contains a single SIP REGISTER request, which ostensibly\
   arrived over UDP in a single datagram.  The packet contains extra\
   octets after the body (which in this case has zero length).  The\
   extra octets happen to look like a SIP INVITE request, but (per\
   section 18.3 of [RFC3261]) they are just spurious noise that must be\
   ignored.\
\
   A SIP element receiving this datagram would handle the REGISTER\
   request normally and ignore the extra bits that look like an INVITE\
   request.  If the element is a proxy choosing to forward the REGISTER,\
   the INVITE octets would not appear in the forwarded request.\
\
\
\
Sparks, et al.               Informational                     [Page 14]\
\
RFC 4475               SIP Torture Test Messages                May 2006\
\
\
      Message Details : dblreq\
\
      REGISTER sip:example.com SIP/2.0\
      To: sip:j.user@example.com\
      From: sip:j.user@example.com;tag=43251j3j324\
      Max-Forwards: 8\
      I: dblreq.0ha0isndaksdj99sdfafnl3lk233412\
      Contact: sip:j.user@host.example.com\
      CSeq: 8 REGISTER\
      Via: SIP/2.0/UDP 192.0.2.125;branch=z9hG4bKkdjuw23492\
      Content-Length: 0\
\
      INVITE sip:joe@example.com SIP/2.0\
      t: sip:joe@example.com\
      From: sip:caller@example.net;tag=141334\
      Max-Forwards: 8\
      Call-ID: dblreq.0ha0isnda977644900765@192.0.2.15\
      CSeq: 8 INVITE\
      Via: SIP/2.0/UDP 192.0.2.15;branch=z9hG4bKkdjuw380234\
      Content-Type: application/sdp\
      Content-Length: 150\
\
      v=0\
      o=mhandley 29739 7272939 IN IP4 192.0.2.15\
      s=-\
      c=IN IP4 192.0.2.15\
      t=0 0\
      m=audio 49217 RTP/AVP 0 12\
      m =video 3227 RTP/AVP 31\
      a=rtpmap:31 LPC\
\
\
\
\
\
\
\
\
\
\
\
\
\
\
\
\
\
\
\
\
\
Sparks, et al.               Informational                     [Page 15]\
\
RFC 4475               SIP Torture Test Messages                May 2006\
\
\
3.1.1.9.  Semicolon-Separated Parameters in URI User Part\
\
   This request has a semicolon-separated parameter contained in the\
   "user" part of the Request-URI (whose value contains an escaped @\
   symbol).  Receiving elements will accept this as a well-formed\
   message.  The Request-URI will parse so that the user part is\
   "user;par=u@example.net".\
\
      Message Details : semiuri\
\
      OPTIONS sip:user;par=u%40example.net@example.com SIP/2.0\
      To: sip:j_user@example.com\
      From: sip:caller@example.org;tag=33242\
      Max-Forwards: 3\
      Call-ID: semiuri.0ha0isndaksdj\
      CSeq: 8 OPTIONS\
      Accept: application/sdp, application/pkcs7-mime,\
              multipart/mixed, multipart/signed,\
              message/sip, message/sipfrag\
      Via: SIP/2.0/UDP 192.0.2.1;branch=z9hG4bKkdjuw\
      l: 0\
\
3.1.1.10.  Varied and Unknown Transport Types\
\
   This request contains Via header field values with all known\
   transport types and exercises the transport extension mechanism.\
   Parsers must accept this message as well formed.  Elements receiving\
   this message would process it exactly as if the 2nd and subsequent\
   header field values specified UDP (or other transport).\
\
      Message Details : transports\
\
      OPTIONS sip:user@example.com SIP/2.0\
      To: sip:user@example.com\
      From: <sip:caller@example.com>;tag=323\
      Max-Forwards: 70\
      Call-ID:  transports.kijh4akdnaqjkwendsasfdj\
      Accept: application/sdp\
      CSeq: 60 OPTIONS\
      Via: SIP/2.0/UDP t1.example.com;branch=z9hG4bKkdjuw\
      Via: SIP/2.0/SCTP t2.example.com;branch=z9hG4bKklasjdhf\
      Via: SIP/2.0/TLS t3.example.com;branch=z9hG4bK2980unddj\
      Via: SIP/2.0/UNKNOWN t4.example.com;branch=z9hG4bKasd0f3en\
      Via: SIP/2.0/TCP t5.example.com;branch=z9hG4bK0a9idfnee\
      l: 0\
\
\
\
\
\
\
Sparks, et al.               Informational                     [Page 16]\
\
RFC 4475               SIP Torture Test Messages                May 2006\
\
\
3.1.1.11.  Multipart MIME Message\
\
   This MESSAGE request contains two body parts.  The second part is\
   binary encoded and contains null (0x00) characters.  Receivers must\
   take care to frame the received message properly.\
\
   Parsers must accept this message as well formed, even if the\
   application above the parser does not support multipart/signed.\
\
   Additional examples of multipart/mime messages, in particular S/MIME\
   messages, are available in the security call flow examples document\
   [SIP-SEC].\
\
      Message Details : mpart01\
\
      MESSAGE sip:kumiko@example.org SIP/2.0\
      <allOneLine>\
      Via: SIP/2.0/UDP 127.0.0.1:5070\
      ;branch=z9hG4bK-d87543-4dade06d0bdb11ee-1--d87543-;rport\
      </allOneLine>\
      Max-Forwards: 70\
      Route: <sip:127.0.0.1:5080>\
      <allOneLine>\
      Identity: r5mwreLuyDRYBi/0TiPwEsY3rEVsk/G2WxhgTV1PF7hHuL\
      IK0YWVKZhKv9Mj8UeXqkMVbnVq37CD+813gvYjcBUaZngQmXc9WNZSDN\
      GCzA+fWl9MEUHWIZo1CeJebdY/XlgKeTa0Olvq0rt70Q5jiSfbqMJmQF\
      teeivUhkMWYUA=\
      </allOneLine>\
      Contact: <sip:fluffy@127.0.0.1:5070>\
      To: <sip:kumiko@example.org>\
      From: <sip:fluffy@example.com>;tag=2fb0dcc9\
      Call-ID: 3d9485ad0c49859b@Zmx1ZmZ5LW1hYy0xNi5sb2NhbA..\
      CSeq: 1 MESSAGE\
      Content-Transfer-Encoding: binary\
      Content-Type: multipart/mixed;boundary=7a9cbec02ceef655\
      Date: Sat, 15 Oct 2005 04:44:56 GMT\
      User-Agent: SIPimp.org/0.2.5 (curses)\
      Content-Length: 553\
\
      --7a9cbec02ceef655\
      Content-Type: text/plain\
      Content-Transfer-Encoding: binary\
\
      Hello\
      --7a9cbec02ceef655\
      Content-Type: application/octet-stream\
      Content-Transfer-Encoding: binary\
\
\
\
\
Sparks, et al.               Informational                     [Page 17]\
\
RFC 4475               SIP Torture Test Messages                May 2006\
\
\
      <hex>\
      3082015206092A86\
      4886F70D010702A08201433082013F02\
      01013109300706052B0E03021A300B06\
      092A864886F70D010701318201203082\
      011C020101307C3070310B3009060355\
      04061302555331133011060355040813\
      0A43616C69666F726E69613111300F06\
      03550407130853616E204A6F7365310E\
      300C060355040A130573697069743129\
      3027060355040B132053697069742054\
      65737420436572746966696361746520\
      417574686F7269747902080195007102\
      330113300706052B0E03021A300D0609\
      2A864886F70D01010105000481808EF4\
      66F948F0522DD2E5978E9D95AAE9F2FE\
      15A06659716292E8DA2AA8D8350A68CE\
      FFAE3CBD2BFF1675DDD5648E593DD647\
      28F26220F7E941749E330D9A15EDABDB\
      93D10C42102E7B7289D29CC0C9AE2EFB\
      C7C0CFF9172F3B027E4FC027E1546DE4\
      B6AA3ABB3E66CCCB5DD6C64B8383149C\
      B8E6FF182D944FE57B65BC99D005\
      </hex>\
      --7a9cbec02ceef655--\
\
3.1.1.12.  Unusual Reason Phrase\
\
   This 200 response contains a reason phrase other than "OK".  The\
   reason phrase is intended for human consumption and may contain any\
   string produced by\
\
       Reason-Phrase   =  *(reserved / unreserved / escaped\
                          / UTF8-NONASCII / UTF8-CONT / SP / HTAB)\
\
   This particular response contains unreserved and non-ascii UTF-8\
   characters.  This response is well formed.  A parser must accept this\
   message.\
\
\
\
\
\
\
\
\
\
\
\
\
\
Sparks, et al.               Informational                     [Page 18]\
\
RFC 4475               SIP Torture Test Messages                May 2006\
\
\
      Message Details : unreason\
\
      <allOneLine>\
      SIP/2.0 200 = 2**3 * 5**2 <hex>D0BDD0BE20D181D182\
      D0BE20D0B4D0B5D0B2D18FD0BDD0BED181D182D0BE20D0B4\
      D0B5D0B2D18FD182D18C202D20D0BFD180D0BED181D182D0\
      BED0B5</hex>\
      </allOneLine>\
      Via: SIP/2.0/UDP 192.0.2.198;branch=z9hG4bK1324923\
      Call-ID: unreason.1234ksdfak3j2erwedfsASdf\
      CSeq: 35 INVITE\
      From: sip:user@example.com;tag=11141343\
      To: sip:user@example.edu;tag=2229\
      Content-Length: 154\
      Content-Type: application/sdp\
      Contact: <sip:user@host198.example.com>\
\
      v=0\
      o=mhandley 29739 7272939 IN IP4 192.0.2.198\
      s=-\
      c=IN IP4 192.0.2.198\
      t=0 0\
      m=audio 49217 RTP/AVP 0 12\
      m=video 3227 RTP/AVP 31\
      a=rtpmap:31 LPC\
\
3.1.1.13.  Empty Reason Phrase\
\
   This well-formed response contains no reason phrase.  A parser must\
   accept this message.  The space character after the reason code is\
   required.  If it were not present, this message could be rejected as\
   invalid (a liberal receiver would accept it anyway).\
\
      Message Details : noreason\
\
      SIP/2.0 100<hex>20</hex>\
      Via: SIP/2.0/UDP 192.0.2.105;branch=z9hG4bK2398ndaoe\
      Call-ID: noreason.asndj203insdf99223ndf\
      CSeq: 35 INVITE\
      From: <sip:user@example.com>;tag=39ansfi3\
      To: <sip:user@example.edu>;tag=902jndnke3\
      Content-Length: 0\
      Contact: <sip:user@host105.example.com>\
\
\
\
\
\
\
\
\
Sparks, et al.               Informational                     [Page 19]\
\
RFC 4475               SIP Torture Test Messages                May 2006\
\
\
3.1.2.  Invalid Messages\
\
   This section contains several invalid messages reflecting errors seen\
   at interoperability events and exploring important edge conditions\
   that can be induced through malformed messages.  This section does\
   not attempt to be a comprehensive list of all types of invalid\
   messages.\
\
3.1.2.1.  Extraneous Header Field Separators\
\
   The Via header field of this request contains additional semicolons\
   and commas without parameters or values.  The Contact header field\
   contains additional semicolons without parameters.  This message is\
   syntactically invalid.\
\
   An element receiving this request should respond with a 400 Bad\
   Request error.\
\
      Message Details : badinv01\
\
      INVITE sip:user@example.com SIP/2.0\
      To: sip:j.user@example.com\
      From: sip:caller@example.net;tag=134161461246\
      Max-Forwards: 7\
      Call-ID: badinv01.0ha0isndaksdjasdf3234nas\
      CSeq: 8 INVITE\
      Via: SIP/2.0/UDP 192.0.2.15;;,;,,\
      Contact: "Joe" <sip:joe@example.org>;;;;\
      Content-Length: 152\
      Content-Type: application/sdp\
\
      v=0\
      o=mhandley 29739 7272939 IN IP4 192.0.2.15\
      s=-\
      c=IN IP4 192.0.2.15\
      t=0 0\
      m=audio 49217 RTP/AVP 0 12\
      m=video 3227 RTP/AVP 31\
      a=rtpmap:31 LPC\
\
3.1.2.2.  Content Length Larger Than Message\
\
   This is a request message with a Content Length that is larger than\
   the actual length of the body.\
\
   When sent over UDP (as this message ostensibly was), the receiving\
   element should respond with a 400 Bad Request error.  If this message\
   arrived over a stream-based transport, such as TCP, there's not much\
\
\
\
Sparks, et al.               Informational                     [Page 20]\
\
RFC 4475               SIP Torture Test Messages                May 2006\
\
\
   the receiving party could do but wait for more data on the stream and\
   close the connection if none is forthcoming within a reasonable\
   period of time.\
\
      Message Details : clerr\
\
      INVITE sip:user@example.com SIP/2.0\
      Max-Forwards: 80\
      To: sip:j.user@example.com\
      From: sip:caller@example.net;tag=93942939o2\
      Contact: <sip:caller@hungry.example.net>\
      Call-ID: clerr.0ha0isndaksdjweiafasdk3\
      CSeq: 8 INVITE\
      Via: SIP/2.0/UDP host5.example.com;branch=z9hG4bK-39234-23523\
      Content-Type: application/sdp\
      Content-Length: 9999\
\
      v=0\
      o=mhandley 29739 7272939 IN IP4 192.0.2.155\
      s=-\
      c=IN IP4 192.0.2.155\
      t=0 0\
      m=audio 49217 RTP/AVP 0 12\
      m=video 3227 RTP/AVP 31\
      a=rtpmap:31 LPC\
\
3.1.2.3.  Negative Content-Length\
\
   This request has a negative value for Content-Length.\
\
   An element receiving this message should respond with an error.  This\
   request appeared over UDP, so the remainder of the datagram can\
   simply be discarded.  If a request like this arrives over TCP, the\
   framing error is not recoverable, and the connection should be\
   closed.  The same behavior is appropriate for messages that arrive\
   without a numeric value in the Content-Length header field, such as\
   the following:\
\
      Content-Length: five\
\
   Implementors should take extra precautions if the technique they\
   choose for converting this ascii field into an integral form can\
   return a negative value.  In particular, the result must not be used\
   as a counter or array index.\
\
\
\
\
\
\
\
Sparks, et al.               Informational                     [Page 21]\
\
RFC 4475               SIP Torture Test Messages                May 2006\
\
\
      Message Details : ncl\
\
      INVITE sip:user@example.com SIP/2.0\
      Max-Forwards: 254\
      To: sip:j.user@example.com\
      From: sip:caller@example.net;tag=32394234\
      Call-ID: ncl.0ha0isndaksdj2193423r542w35\
      CSeq: 0 INVITE\
      Via: SIP/2.0/UDP 192.0.2.53;branch=z9hG4bKkdjuw\
      Contact: <sip:caller@example53.example.net>\
      Content-Type: application/sdp\
      Content-Length: -999\
\
      v=0\
      o=mhandley 29739 7272939 IN IP4 192.0.2.53\
      s=-\
      c=IN IP4 192.0.2.53\
      t=0 0\
      m=audio 49217 RTP/AVP 0 12\
      m=video 3227 RTP/AVP 31\
      a=rtpmap:31 LPC\
\
3.1.2.4.  Request Scalar Fields with Overlarge Values\
\
   This request contains several scalar header field values outside\
   their legal range.\
\
      o  The CSeq sequence number is >2**32-1.\
\
      o  The Max-Forwards value is >255.\
\
      o  The Expires value is >2**32-1.\
\
      o  The Contact expires parameter value is >2**32-1.\
\
   An element receiving this request should respond with a 400 Bad\
   Request due to the CSeq error.  If only the Max-Forwards field were\
   in error, the element could choose to process the request as if the\
   field were absent.  If only the expiry values were in error, the\
   element could treat them as if they contained the default values for\
   expiration (3600 in this case).\
\
   Other scalar request fields that may contain aberrant values include,\
   but are not limited to, the Contact q value, the Timestamp value, and\
   the Via ttl parameter.\
\
\
\
\
\
\
Sparks, et al.               Informational                     [Page 22]\
\
RFC 4475               SIP Torture Test Messages                May 2006\
\
\
      Message Details : scalar02\
\
      REGISTER sip:example.com SIP/2.0\
      Via: SIP/2.0/TCP host129.example.com;branch=z9hG4bK342sdfoi3\
      To: <sip:user@example.com>\
      From: <sip:user@example.com>;tag=239232jh3\
      CSeq: 36893488147419103232 REGISTER\
      Call-ID: scalar02.23o0pd9vanlq3wnrlnewofjas9ui32\
      Max-Forwards: 300\
      Expires: 1<repeat count=100>0</repeat>\
      Contact: <sip:user@host129.example.com>\
        ;expires=280297596632815\
      Content-Length: 0\
\
3.1.2.5.  Response Scalar Fields with Overlarge Values\
\
   This response contains several scalar header field values outside\
   their legal range.\
\
   o  The CSeq sequence number is >2**32-1.\
\
   o  The Retry-After field is unreasonably large (note that RFC 3261\
      does not define a legal range for this field).\
\
   o  The Warning field has a warning-value with more than 3 digits.\
\
   An element receiving this response will simply discard it.\
\
      Message Details : scalarlg\
\
      SIP/2.0 503 Service Unavailable\
      <allOneLine>\
      Via: SIP/2.0/TCP host129.example.com\
      ;branch=z9hG4bKzzxdiwo34sw\
      ;received=192.0.2.129\
      </allOneLine>\
      To: <sip:user@example.com>\
      From: <sip:other@example.net>;tag=2easdjfejw\
      CSeq: 9292394834772304023312 OPTIONS\
      Call-ID: scalarlg.noase0of0234hn2qofoaf0232aewf2394r\
      Retry-After: 949302838503028349304023988\
      Warning: 1812 overture "In Progress"\
      Content-Length: 0\
\
\
\
\
\
\
\
\
Sparks, et al.               Informational                     [Page 23]\
\
RFC 4475               SIP Torture Test Messages                May 2006\
\
\
3.1.2.6.  Unterminated Quoted String in Display Name\
\
   This is a request with an unterminated quote in the display name of\
   the To field.  An element receiving this request should return a 400\
   Bad Request error.\
\
   An element could attempt to infer a terminating quote and accept the\
   message.  Such an element needs to take care that it makes a\
   reasonable inference when it encounters\
\
      To: "Mr J. User <sip:j.user@example.com> <sip:realj@example.net>\
\
      Message Details : quotbal\
\
      INVITE sip:user@example.com SIP/2.0\
      To: "Mr. J. User <sip:j.user@example.com>\
      From: sip:caller@example.net;tag=93334\
      Max-Forwards: 10\
      Call-ID: quotbal.aksdj\
      Contact: <sip:caller@host59.example.net>\
      CSeq: 8 INVITE\
      Via: SIP/2.0/UDP 192.0.2.59:5050;branch=z9hG4bKkdjuw39234\
      Content-Type: application/sdp\
      Content-Length: 152\
\
      v=0\
      o=mhandley 29739 7272939 IN IP4 192.0.2.15\
      s=-\
      c=IN IP4 192.0.2.15\
      t=0 0\
      m=audio 49217 RTP/AVP 0 12\
      m=video 3227 RTP/AVP 31\
      a=rtpmap:31 LPC\
\
\
\
\
\
\
\
\
\
\
\
\
\
\
\
\
\
\
Sparks, et al.               Informational                     [Page 24]\
\
RFC 4475               SIP Torture Test Messages                May 2006\
\
\
3.1.2.7.  <> Enclosing Request-URI\
\
   This INVITE request is invalid because the Request-URI has been\
   enclosed within in "<>".\
\
   It is reasonable always to reject a request with this error with a\
   400 Bad Request.  Elements attempting to be liberal with what they\
   accept may choose to ignore the brackets.  If the element forwards\
   the request, it must not include the brackets in the messages it\
   sends.\
\
      Message Details : ltgtruri\
\
      INVITE <sip:user@example.com> SIP/2.0\
      To: sip:user@example.com\
      From: sip:caller@example.net;tag=39291\
      Max-Forwards: 23\
      Call-ID: ltgtruri.1@192.0.2.5\
      CSeq: 1 INVITE\
      Via: SIP/2.0/UDP 192.0.2.5\
      Contact: <sip:caller@host5.example.net>\
      Content-Type: application/sdp\
      Content-Length: 159\
\
      v=0\
      o=mhandley 29739 7272939 IN IP4 192.0.2.5\
      s=-\
      c=IN IP4 192.0.2.5\
      t=3149328700 0\
      m=audio 49217 RTP/AVP 0 12\
      m=video 3227 RTP/AVP 31\
      a=rtpmap:31 LPC\
\
\
\
\
\
\
\
\
\
\
\
\
\
\
\
\
\
\
\
Sparks, et al.               Informational                     [Page 25]\
\
RFC 4475               SIP Torture Test Messages                May 2006\
\
\
3.1.2.8.  Malformed SIP Request-URI (embedded LWS)\
\
   This INVITE has illegal LWS within the Request-URI.\
\
   An element receiving this request should respond with a 400 Bad\
   Request.\
\
   An element could attempt to ignore the embedded LWS for those schemes\
   (like SIP) where doing so would not introduce ambiguity.\
\
      Message Details : lwsruri\
\
      INVITE sip:user@example.com; lr SIP/2.0\
      To: sip:user@example.com;tag=3xfe-9921883-z9f\
      From: sip:caller@example.net;tag=231413434\
      Max-Forwards: 5\
      Call-ID: lwsruri.asdfasdoeoi2323-asdfwrn23-asd834rk423\
      CSeq: 2130706432 INVITE\
      Via: SIP/2.0/UDP 192.0.2.1:5060;branch=z9hG4bKkdjuw2395\
      Contact: <sip:caller@host1.example.net>\
      Content-Type: application/sdp\
      Content-Length: 159\
\
      v=0\
      o=mhandley 29739 7272939 IN IP4 192.0.2.1\
      s=-\
      c=IN IP4 192.0.2.1\
      t=3149328700 0\
      m=audio 49217 RTP/AVP 0 12\
      m=video 3227 RTP/AVP 31\
      a=rtpmap:31 LPC\
\
\
\
\
\
\
\
\
\
\
\
\
\
\
\
\
\
\
\
\
Sparks, et al.               Informational                     [Page 26]\
\
RFC 4475               SIP Torture Test Messages                May 2006\
\
\
3.1.2.9.  Multiple SP Separating Request-Line Elements\
\
   This INVITE has illegal multiple SP characters between elements of\
   the start line.\
\
   It is acceptable to reject this request as malformed.  An element\
   that is liberal in what it accepts may ignore these extra SP\
   characters when processing the request.  If the element forwards the\
   request, it must not include these extra SP characters in the\
   messages it sends.\
\
      Message Details : lwsstart\
\
      INVITE  sip:user@example.com  SIP/2.0\
      Max-Forwards: 8\
      To: sip:user@example.com\
      From: sip:caller@example.net;tag=8814\
      Call-ID: lwsstart.dfknq234oi243099adsdfnawe3@example.com\
      CSeq: 1893884 INVITE\
      Via: SIP/2.0/UDP host1.example.com;branch=z9hG4bKkdjuw3923\
      Contact: <sip:caller@host1.example.net>\
      Content-Type: application/sdp\
      Content-Length: 150\
\
      v=0\
      o=mhandley 29739 7272939 IN IP4 192.0.2.1\
      s=-\
      c=IN IP4 192.0.2.1\
      t=0 0\
      m=audio 49217 RTP/AVP 0 12\
      m=video 3227 RTP/AVP 31\
      a=rtpmap:31 LPC\
\
\
\
\
\
\
\
\
\
\
\
\
\
\
\
\
\
\
\
Sparks, et al.               Informational                     [Page 27]\
\
RFC 4475               SIP Torture Test Messages                May 2006\
\
\
3.1.2.10.  SP Characters at End of Request-Line\
\
   This OPTIONS request contains SP characters between the SIP-Version\
   field and the CRLF terminating the Request-Line.\
\
   It is acceptable to reject this request as malformed.  An element\
   that is liberal in what it accepts may ignore these extra SP\
   characters when processing the request.  If the element forwards the\
   request, it must not include these extra SP characters in the\
   messages it sends.\
\
      Message Details : trws\
\
      OPTIONS sip:remote-target@example.com SIP/2.0<hex>2020</hex>\
      Via: SIP/2.0/TCP host1.example.com;branch=z9hG4bK299342093\
      To: <sip:remote-target@example.com>\
      From: <sip:local-resource@example.com>;tag=329429089\
      Call-ID: trws.oicu34958239neffasdhr2345r\
      Accept: application/sdp\
      CSeq: 238923 OPTIONS\
      Max-Forwards: 70\
      Content-Length: 0\
\
\
\
\
\
\
\
\
\
\
\
\
\
\
\
\
\
\
\
\
\
\
\
\
\
\
\
\
\
Sparks, et al.               Informational                     [Page 28]\
\
RFC 4475               SIP Torture Test Messages                May 2006\
\
\
3.1.2.11.  Escaped Headers in SIP Request-URI\
\
   This INVITE is malformed, as the SIP Request-URI contains escaped\
   headers.\
\
   It is acceptable for an element to reject this request with a 400 Bad\
   Request.  An element could choose to be liberal in what it accepts\
   and ignore the escaped headers.  If the element is a proxy, the\
   escaped headers must not appear in the Request-URI of the forwarded\
   request (and most certainly must not be translated into the actual\
   header of the forwarded request).\
\
      Message Details : escruri\
\
      INVITE sip:user@example.com?Route=%3Csip:example.com%3E SIP/2.0\
      To: sip:user@example.com\
      From: sip:caller@example.net;tag=341518\
      Max-Forwards: 7\
      Contact: <sip:caller@host39923.example.net>\
      Call-ID: escruri.23940-asdfhj-aje3br-234q098w-fawerh2q-h4n5\
      CSeq: 149209342 INVITE\
      Via: SIP/2.0/UDP host-of-the-hour.example.com;branch=z9hG4bKkdjuw\
      Content-Type: application/sdp\
      Content-Length: 150\
\
      v=0\
      o=mhandley 29739 7272939 IN IP4 192.0.2.1\
      s=-\
      c=IN IP4 192.0.2.1\
      t=0 0\
      m=audio 49217 RTP/AVP 0 12\
      m=video 3227 RTP/AVP 31\
      a=rtpmap:31 LPC\
\
\
\
\
\
\
\
\
\
\
\
\
\
\
\
\
\
\
Sparks, et al.               Informational                     [Page 29]\
\
RFC 4475               SIP Torture Test Messages                May 2006\
\
\
3.1.2.12.  Invalid Time Zone in Date Header Field\
\
   This INVITE is invalid, as it contains a non-GMT time zone in the SIP\
   Date header field.\
\
   It is acceptable to reject this request as malformed (though an\
   element shouldn't do that unless the contents of the Date header\
   field were actually important to its processing).  An element wishing\
   to be liberal in what it accepts could ignore this value altogether\
   if it wasn't going to use the Date header field anyway.  Otherwise,\
   it could attempt to interpret this date and adjust it to GMT.\
\
   RFC 3261 explicitly defines the only acceptable time zone designation\
   as "GMT".  "UT", while synonymous with GMT per [RFC2822], is not\
   valid.  "UTC" and "UCT" are also invalid.\
\
      Message Details : baddate\
\
      INVITE sip:user@example.com SIP/2.0\
      To: sip:user@example.com\
      From: sip:caller@example.net;tag=2234923\
      Max-Forwards: 70\
      Call-ID: baddate.239423mnsadf3j23lj42--sedfnm234\
      CSeq: 1392934 INVITE\
      Via: SIP/2.0/UDP host.example.com;branch=z9hG4bKkdjuw\
      Date: Fri, 01 Jan 2010 16:00:00 EST\
      Contact: <sip:caller@host5.example.net>\
      Content-Type: application/sdp\
      Content-Length: 150\
\
      v=0\
      o=mhandley 29739 7272939 IN IP4 192.0.2.5\
      s=-\
      c=IN IP4 192.0.2.5\
      t=0 0\
      m=audio 49217 RTP/AVP 0 12\
      m=video 3227 RTP/AVP 31\
      a=rtpmap:31 LPC\
\
\
\
\
\
\
\
\
\
\
\
\
\
Sparks, et al.               Informational                     [Page 30]\
\
RFC 4475               SIP Torture Test Messages                May 2006\
\
\
3.1.2.13.  Failure to Enclose name-addr URI in <>\
\
   This REGISTER request is malformed.  The SIP URI contained in the\
   Contact Header field has an escaped header, so the field must be in\
   name-addr form (which implies that the URI must be enclosed in <>).\
\
   It is reasonable for an element receiving this request to respond\
   with a 400 Bad Request.  An element choosing to be liberal in what it\
   accepts could infer the angle brackets since there is no ambiguity in\
   this example.  In general, that won't be possible.\
\
      Message Details : regbadct\
\
      REGISTER sip:example.com SIP/2.0\
      To: sip:user@example.com\
      From: sip:user@example.com;tag=998332\
      Max-Forwards: 70\
      Call-ID: regbadct.k345asrl3fdbv@10.0.0.1\
      CSeq: 1 REGISTER\
      Via: SIP/2.0/UDP 135.180.130.133:5060;branch=z9hG4bKkdjuw\
      Contact: sip:user@example.com?Route=%3Csip:sip.example.com%3E\
      l: 0\
\
3.1.2.14.  Spaces within addr-spec\
\
   This request is malformed, since the addr-spec in the To header field\
   contains spaces.  Parsers receiving this request must not break.  It\
   is reasonable to reject this request with a 400 Bad Request response.\
   Elements attempting to be liberal may ignore the spaces.\
\
      Message Details : badaspec\
\
      OPTIONS sip:user@example.org SIP/2.0\
      Via: SIP/2.0/UDP host4.example.com:5060;branch=z9hG4bKkdju43234\
      Max-Forwards: 70\
      From: "Bell, Alexander" <sip:a.g.bell@example.com>;tag=433423\
      To: "Watson, Thomas" < sip:t.watson@example.org >\
      Call-ID: badaspec.sdf0234n2nds0a099u23h3hnnw009cdkne3\
      Accept: application/sdp\
      CSeq: 3923239 OPTIONS\
      l: 0\
\
\
\
\
\
\
\
\
\
\
Sparks, et al.               Informational                     [Page 31]\
\
RFC 4475               SIP Torture Test Messages                May 2006\
\
\
3.1.2.15.  Non-token Characters in Display Name\
\
   This OPTIONS request is malformed, since the display names in the To\
   and From header fields contain non-token characters but are unquoted.\
\
   It is reasonable always to reject this kind of error with a 400 Bad\
   Request response.\
\
   An element may attempt to be liberal in what it receives and infer\
   the missing quotes.  If this element were a proxy, it must not\
   propagate the error into the request it forwards.  As a consequence,\
   if the fields are covered by a signature, there's not much point in\
   trying to be liberal - the message should simply be rejected.\
\
      Message Details : baddn\
\
      OPTIONS sip:t.watson@example.org SIP/2.0\
      Via:     SIP/2.0/UDP c.example.com:5060;branch=z9hG4bKkdjuw\
      Max-Forwards:      70\
      From:    Bell, Alexander <sip:a.g.bell@example.com>;tag=43\
      To:      Watson, Thomas <sip:t.watson@example.org>\
      Call-ID: baddn.31415@c.example.com\
      Accept: application/sdp\
      CSeq:    3923239 OPTIONS\
      l: 0\
\
3.1.2.16.  Unknown Protocol Version\
\
   To an element implementing [RFC3261], this request is malformed due\
   to its high version number.\
\
   The element should respond to the request with a 505 Version Not\
   Supported error.\
\
      Message Details : badvers\
\
      OPTIONS sip:t.watson@example.org SIP/7.0\
      Via:     SIP/7.0/UDP c.example.com;branch=z9hG4bKkdjuw\
      Max-Forwards:     70\
      From:    A. Bell <sip:a.g.bell@example.com>;tag=qweoiqpe\
      To:      T. Watson <sip:t.watson@example.org>\
      Call-ID: badvers.31417@c.example.com\
      CSeq:    1 OPTIONS\
      l: 0\
\
\
\
\
\
\
\
Sparks, et al.               Informational                     [Page 32]\
\
RFC 4475               SIP Torture Test Messages                May 2006\
\
\
3.1.2.17.  Start Line and CSeq Method Mismatch\
\
   This request has mismatching values for the method in the start line\
   and the CSeq header field.  Any element receiving this request will\
   respond with a 400 Bad Request.\
\
      Message Details : mismatch01\
\
      OPTIONS sip:user@example.com SIP/2.0\
      To: sip:j.user@example.com\
      From: sip:caller@example.net;tag=34525\
      Max-Forwards: 6\
      Call-ID: mismatch01.dj0234sxdfl3\
      CSeq: 8 INVITE\
      Via: SIP/2.0/UDP host.example.com;branch=z9hG4bKkdjuw\
      l: 0\
\
3.1.2.18.  Unknown Method with CSeq Method Mismatch\
\
   This message has an unknown method in the start line, and a CSeq\
   method tag that does not match.\
\
   Any element receiving this response should respond with a 501 Not\
   Implemented.  A 400 Bad Request is also acceptable, but choosing a\
   501 (particularly at proxies) has better future-proof\
   characteristics.\
\
      Message Details : mismatch02\
\
      NEWMETHOD sip:user@example.com SIP/2.0\
      To: sip:j.user@example.com\
      From: sip:caller@example.net;tag=34525\
      Max-Forwards: 6\
      Call-ID: mismatch02.dj0234sxdfl3\
      CSeq: 8 INVITE\
      Contact: <sip:caller@host.example.net>\
      Via: SIP/2.0/UDP host.example.net;branch=z9hG4bKkdjuw\
      Content-Type: application/sdp\
      l: 138\
\
      v=0\
      o=mhandley 29739 7272939 IN IP4 192.0.2.1\
      c=IN IP4 192.0.2.1\
      m=audio 49217 RTP/AVP 0 12\
      m=video 3227 RTP/AVP 31\
      a=rtpmap:31 LPC\
\
\
\
\
\
Sparks, et al.               Informational                     [Page 33]\
\
RFC 4475               SIP Torture Test Messages                May 2006\
\
\
3.1.2.19.  Overlarge Response Code\
\
   This response has a response code larger than 699.  An element\
   receiving this response should simply drop it.\
\
      Message Details : bigcode\
\
      SIP/2.0 4294967301 better not break the receiver\
      Via: SIP/2.0/UDP 192.0.2.105;branch=z9hG4bK2398ndaoe\
      Call-ID: bigcode.asdof3uj203asdnf3429uasdhfas3ehjasdfas9i\
      CSeq: 353494 INVITE\
      From: <sip:user@example.com>;tag=39ansfi3\
      To: <sip:user@example.edu>;tag=902jndnke3\
      Content-Length: 0\
      Contact: <sip:user@host105.example.com>\
\
3.2.  Transaction Layer Semantics\
\
   This section contains tests that exercise an implementation's parser\
   and transaction-layer logic.\
\
3.2.1.  Missing Transaction Identifier\
\
   This request indicates support for RFC 3261-style transaction\
   identifiers by providing the z9hG4bK prefix to the branch parameter,\
   but it provides no identifier.  A parser must not break when\
   receiving this message.  An element receiving this request could\
   reject the request with a 400 Response (preferably statelessly, as\
   other requests from the source are likely also to have a malformed\
   branch parameter), or it could fall back to the RFC 2543-style\
   transaction identifier.\
\
      Message Details : badbranch\
\
      OPTIONS sip:user@example.com SIP/2.0\
      To: sip:user@example.com\
      From: sip:caller@example.org;tag=33242\
      Max-Forwards: 3\
      Via: SIP/2.0/UDP 192.0.2.1;branch=z9hG4bK\
      Accept: application/sdp\
      Call-ID: badbranch.sadonfo23i420jv0as0derf3j3n\
      CSeq: 8 OPTIONS\
      l: 0\
\
\
\
\
\
\
\
\
Sparks, et al.               Informational                     [Page 34]\
\
RFC 4475               SIP Torture Test Messages                May 2006\
\
\
3.3.  Application-Layer Semantics\
\
   This section contains tests that exercise an implementation's parser\
   and application-layer logic.\
\
3.3.1.  Missing Required Header Fields\
\
   This request contains no Call-ID, From, or To header fields.\
\
   An element receiving this message must not break because of the\
   missing information.  Ideally, it will respond with a 400 Bad Request\
   error.\
\
      Message Details : insuf\
\
      INVITE sip:user@example.com SIP/2.0\
      CSeq: 193942 INVITE\
      Via: SIP/2.0/UDP 192.0.2.95;branch=z9hG4bKkdj.insuf\
      Content-Type: application/sdp\
      l: 152\
\
      v=0\
      o=mhandley 29739 7272939 IN IP4 192.0.2.95\
      s=-\
      c=IN IP4 192.0.2.95\
      t=0 0\
      m=audio 49217 RTP/AVP 0 12\
      m=video 3227 RTP/AVP 31\
      a=rtpmap:31 LPC\
\
\
\
\
\
\
\
\
\
\
\
\
\
\
\
\
\
\
\
\
\
\
Sparks, et al.               Informational                     [Page 35]\
\
RFC 4475               SIP Torture Test Messages                May 2006\
\
\
3.3.2.  Request-URI with Unknown Scheme\
\
   This OPTIONS contains an unknown URI scheme in the Request-URI.  A\
   parser must accept this as a well-formed SIP request.\
\
   An element receiving this request will reject it with a 416\
   Unsupported URI Scheme response.\
\
   Some early implementations attempt to look at the contents of the To\
   header field to determine how to route this kind of request.  That is\
   an error.  Despite the fact that the To header field and the Request\
   URI frequently look alike in simplistic first-hop messages, the To\
   header field contains no routing information.\
\
      Message Details : unkscm\
\
      OPTIONS nobodyKnowsThisScheme:totallyopaquecontent SIP/2.0\
      To: sip:user@example.com\
      From: sip:caller@example.net;tag=384\
      Max-Forwards: 3\
      Call-ID: unkscm.nasdfasser0q239nwsdfasdkl34\
      CSeq: 3923423 OPTIONS\
      Via: SIP/2.0/TCP host9.example.com;branch=z9hG4bKkdjuw39234\
      Content-Length: 0\
\
3.3.3.  Request-URI with Known but Atypical Scheme\
\
   This OPTIONS contains an Request-URI with an IANA-registered scheme\
   that does not commonly appear in Request-URIs of SIP requests.  A\
   parser must accept this as a well-formed SIP request.\
\
   If an element will never accept this scheme as meaningful in a\
   Request-URI, it is appropriate to treat it as unknown and return a\
   416 Unsupported URI Scheme response.  If the element might accept\
   some URIs with this scheme, then a 404 Not Found is appropriate for\
   those URIs it doesn't accept.\
\
      Message Details : novelsc\
\
      OPTIONS soap.beep://192.0.2.103:3002 SIP/2.0\
      To: sip:user@example.com\
      From: sip:caller@example.net;tag=384\
      Max-Forwards: 3\
      Call-ID: novelsc.asdfasser0q239nwsdfasdkl34\
      CSeq: 3923423 OPTIONS\
      Via: SIP/2.0/TCP host9.example.com;branch=z9hG4bKkdjuw39234\
      Content-Length: 0\
\
\
\
\
Sparks, et al.               Informational                     [Page 36]\
\
RFC 4475               SIP Torture Test Messages                May 2006\
\
\
3.3.4.  Unknown URI Schemes in Header Fields\
\
   This message contains registered schemes in the To, From, and Contact\
   header fields of a request.  The message is syntactically valid.\
   Parsers must not fail when receiving this message.\
\
   Proxies should treat this message as they would any other request for\
   this URI.  A registrar would reject this request with a 400 Bad\
   Request response, since the To: header field is required to contain a\
   SIP or SIPS URI as an AOR.\
\
      Message Details : unksm2\
\
      REGISTER sip:example.com SIP/2.0\
      To: isbn:2983792873\
      From: <http://www.example.com>;tag=3234233\
      Call-ID: unksm2.daksdj@hyphenated-host.example.com\
      CSeq: 234902 REGISTER\
      Max-Forwards: 70\
      Via: SIP/2.0/UDP 192.0.2.21:5060;branch=z9hG4bKkdjuw\
      Contact: <name:John_Smith>\
      l: 0\
\
3.3.5.  Proxy-Require and Require\
\
   This request tests proper implementation of SIP's Proxy-Require and\
   Require extension mechanisms.\
\
   Any element receiving this request will respond with a 420 Bad\
   Extension response, containing an Unsupported header field listing\
   these features from either the Require or Proxy-Require header field,\
   depending on the role in which the element is responding.\
\
      Message Details : bext01\
\
      OPTIONS sip:user@example.com SIP/2.0\
      To: sip:j_user@example.com\
      From: sip:caller@example.net;tag=242etr\
      Max-Forwards: 6\
      Call-ID: bext01.0ha0isndaksdj\
      Require: nothingSupportsThis, nothingSupportsThisEither\
      Proxy-Require: noProxiesSupportThis, norDoAnyProxiesSupportThis\
      CSeq: 8 OPTIONS\
      Via: SIP/2.0/TLS fold-and-staple.example.com;branch=z9hG4bKkdjuw\
      Content-Length: 0\
\
\
\
\
\
\
Sparks, et al.               Informational                     [Page 37]\
\
RFC 4475               SIP Torture Test Messages                May 2006\
\
\
3.3.6.  Unknown Content-Type\
\
   This INVITE request contains a body of unknown type.  It is\
   syntactically valid.  A parser must not fail when receiving it.\
\
   A proxy receiving this request would process it just as it would any\
   other INVITE.  An endpoint receiving this request would reject it\
   with a 415 Unsupported Media Type error.\
\
      Message Details : invut\
\
      INVITE sip:user@example.com SIP/2.0\
      Contact: <sip:caller@host5.example.net>\
      To: sip:j.user@example.com\
      From: sip:caller@example.net;tag=8392034\
      Max-Forwards: 70\
      Call-ID: invut.0ha0isndaksdjadsfij34n23d\
      CSeq: 235448 INVITE\
      Via: SIP/2.0/UDP somehost.example.com;branch=z9hG4bKkdjuw\
      Content-Type: application/unknownformat\
      Content-Length: 40\
\
      <audio>\
       <pcmu port="443"/>\
      </audio>\
\
3.3.7.  Unknown Authorization Scheme\
\
   This REGISTER request contains an Authorization header field with an\
   unknown scheme.  The request is well formed.  A parser must not fail\
   when receiving it.\
\
   A proxy will treat this request as it would any other REGISTER.  If\
   it forwards the request, it will include this Authorization header\
   field unmodified in the forwarded messages.\
\
   A registrar that does not care about challenge-response\
   authentication will simply ignore the Authorization header field,\
   processing this registration as if the field were not present.  A\
   registrar that does care about challenge-response authentication will\
   reject this request with a 401, issuing a new challenge with a scheme\
   it understands.\
\
   Endpoints choosing not to act as registrars will simply reject the\
   request.  A 405 Method Not Allowed is appropriate.\
\
\
\
\
\
\
Sparks, et al.               Informational                     [Page 38]\
\
RFC 4475               SIP Torture Test Messages                May 2006\
\
\
      Message Details : regaut01\
\
      REGISTER sip:example.com SIP/2.0\
      To: sip:j.user@example.com\
      From: sip:j.user@example.com;tag=87321hj23128\
      Max-Forwards: 8\
      Call-ID: regaut01.0ha0isndaksdj\
      CSeq: 9338 REGISTER\
      Via: SIP/2.0/TCP 192.0.2.253;branch=z9hG4bKkdjuw\
      Authorization: NoOneKnowsThisScheme opaque-data=here\
      Content-Length:0\
\
3.3.8.  Multiple Values in Single Value Required Fields\
\
   The message contains a request with multiple Call-ID, To, From, Max-\
   Forwards, and CSeq values.  An element receiving this request must\
   not break.\
\
   An element receiving this request would respond with a 400 Bad\
   Request error.\
\
      Message Details : multi01\
\
      INVITE sip:user@company.com SIP/2.0\
      Contact: <sip:caller@host25.example.net>\
      Via: SIP/2.0/UDP 192.0.2.25;branch=z9hG4bKkdjuw\
      Max-Forwards: 70\
      CSeq: 5 INVITE\
      Call-ID: multi01.98asdh@192.0.2.1\
      CSeq: 59 INVITE\
      Call-ID: multi01.98asdh@192.0.2.2\
      From: sip:caller@example.com;tag=3413415\
      To: sip:user@example.com\
      To: sip:other@example.net\
      From: sip:caller@example.net;tag=2923420123\
      Content-Type: application/sdp\
      l: 154\
      Contact: <sip:caller@host36.example.net>\
      Max-Forwards: 5\
\
      v=0\
      o=mhandley 29739 7272939 IN IP4 192.0.2.25\
      s=-\
      c=IN IP4 192.0.2.25\
      t=0 0\
      m=audio 49217 RTP/AVP 0 12\
      m=video 3227 RTP/AVP 31\
      a=rtpmap:31 LPC\
\
\
\
Sparks, et al.               Informational                     [Page 39]\
\
RFC 4475               SIP Torture Test Messages                May 2006\
\
\
3.3.9.  Multiple Content-Length Values\
\
   Multiple conflicting Content-Length header field values appear in\
   this request.\
\
   From a framing perspective, this situation is equivalent to an\
   invalid Content-Length value (or no value at all).\
\
   An element receiving this message should respond with an error.  This\
   request appeared over UDP, so the remainder of the datagram can\
   simply be discarded.  If a request like this arrives over TCP, the\
   framing error is not recoverable, and the connection should be\
   closed.\
\
      Message Details : mcl01\
\
      OPTIONS sip:user@example.com SIP/2.0\
      Via: SIP/2.0/UDP host5.example.net;branch=z9hG4bK293423\
      To: sip:user@example.com\
      From: sip:other@example.net;tag=3923942\
      Call-ID: mcl01.fhn2323orihawfdoa3o4r52o3irsdf\
      CSeq: 15932 OPTIONS\
      Content-Length: 13\
      Max-Forwards: 60\
      Content-Length: 5\
      Content-Type: text/plain\
\
      There's no way to know how many octets are supposed to be here.\
\
3.3.10.  200 OK Response with Broadcast Via Header Field Value\
\
   This message is a response with a 2nd Via header field value's sent-\
   by containing 255.255.255.255.  The message is well formed; parsers\
   must not fail when receiving it.\
\
   Per [RFC3261], an endpoint receiving this message should simply\
   discard it.\
\
   If a proxy followed normal response processing rules blindly, it\
   would forward this response to the broadcast address.  To protect\
   against this as an avenue of attack, proxies should drop such\
   responses.\
\
\
\
\
\
\
\
\
\
Sparks, et al.               Informational                     [Page 40]\
\
RFC 4475               SIP Torture Test Messages                May 2006\
\
\
      Message Details : bcast\
\
      SIP/2.0 200 OK\
      Via: SIP/2.0/UDP 192.0.2.198;branch=z9hG4bK1324923\
      Via: SIP/2.0/UDP 255.255.255.255;branch=z9hG4bK1saber23\
      Call-ID: bcast.0384840201234ksdfak3j2erwedfsASdf\
      CSeq: 35 INVITE\
      From: sip:user@example.com;tag=11141343\
      To: sip:user@example.edu;tag=2229\
      Content-Length: 154\
      Content-Type: application/sdp\
      Contact: <sip:user@host28.example.com>\
\
      v=0\
      o=mhandley 29739 7272939 IN IP4 192.0.2.198\
      s=-\
      c=IN IP4 192.0.2.198\
      t=0 0\
      m=audio 49217 RTP/AVP 0 12\
      m=video 3227 RTP/AVP 31\
      a=rtpmap:31 LPC\
\
3.3.11.  Max-Forwards of Zero\
\
   This is a legal SIP request with the Max-Forwards header field value\
   set to zero.\
\
   A proxy should not forward the request and should respond 483 (Too\
   Many Hops).  An endpoint should process the request as if the Max-\
   Forwards field value were still positive.\
\
      Message Details : zeromf\
\
      OPTIONS sip:user@example.com SIP/2.0\
      To: sip:user@example.com\
      From: sip:caller@example.net;tag=3ghsd41\
      Call-ID: zeromf.jfasdlfnm2o2l43r5u0asdfas\
      CSeq: 39234321 OPTIONS\
      Via: SIP/2.0/UDP host1.example.com;branch=z9hG4bKkdjuw2349i\
      Max-Forwards: 0\
      Content-Length: 0\
\
\
\
\
\
\
\
\
\
\
Sparks, et al.               Informational                     [Page 41]\
\
RFC 4475               SIP Torture Test Messages                May 2006\
\
\
3.3.12.  REGISTER with a Contact Header Parameter\
\
   This register request contains a contact where the 'unknownparam'\
   parameter must be interpreted as a contact-param and not a url-param.\
\
   This REGISTER should succeed.  The response must not include\
   "unknownparam" as a url-parameter for this binding.  Likewise,\
   "unknownparam" must not appear as a url-parameter in any binding\
   during subsequent fetches.\
\
   Behavior is the same, of course, for any known contact-param\
   parameter names.\
\
      Message Details : cparam01\
\
      REGISTER sip:example.com SIP/2.0\
      Via: SIP/2.0/UDP saturn.example.com:5060;branch=z9hG4bKkdjuw\
      Max-Forwards: 70\
      From: sip:watson@example.com;tag=DkfVgjkrtMwaerKKpe\
      To: sip:watson@example.com\
      Call-ID: cparam01.70710@saturn.example.com\
      CSeq: 2 REGISTER\
      Contact: sip:+19725552222@gw1.example.net;unknownparam\
      l: 0\
\
3.3.13.  REGISTER with a url-parameter\
\
   This register request contains a contact where the URI has an unknown\
   parameter.\
\
   The register should succeed, and a subsequent retrieval of the\
   registration must include "unknownparam" as a url-parameter.\
\
   Behavior is the same, of course, for any known url-parameter names.\
\
      Message Details : cparam02\
\
      REGISTER sip:example.com SIP/2.0\
      Via: SIP/2.0/UDP saturn.example.com:5060;branch=z9hG4bKkdjuw\
      Max-Forwards: 70\
      From: sip:watson@example.com;tag=838293\
      To: sip:watson@example.com\
      Call-ID: cparam02.70710@saturn.example.com\
      CSeq: 3 REGISTER\
      Contact: <sip:+19725552222@gw1.example.net;unknownparam>\
      l: 0\
\
\
\
\
\
Sparks, et al.               Informational                     [Page 42]\
\
RFC 4475               SIP Torture Test Messages                May 2006\
\
\
3.3.14.  REGISTER with a URL Escaped Header\
\
   This register request contains a contact where the URI has an escaped\
   header.\
\
   The register should succeed, and a subsequent retrieval of the\
   registration must include the escaped Route header in the contact URI\
   for this binding.\
\
      Message Details : regescrt\
\
      REGISTER sip:example.com SIP/2.0\
      To: sip:user@example.com\
      From: sip:user@example.com;tag=8\
      Max-Forwards: 70\
      Call-ID: regescrt.k345asrl3fdbv@192.0.2.1\
      CSeq: 14398234 REGISTER\
      Via: SIP/2.0/UDP host5.example.com;branch=z9hG4bKkdjuw\
      M: <sip:user@example.com?Route=%3Csip:sip.example.com%3E>\
      L:0\
\
\
\
\
\
\
\
\
\
\
\
\
\
\
\
\
\
\
\
\
\
\
\
\
\
\
\
\
\
\
\
Sparks, et al.               Informational                     [Page 43]\
\
RFC 4475               SIP Torture Test Messages                May 2006\
\
\
3.3.15.  Unacceptable Accept Offering\
\
   This request indicates that the response must contain a body in an\
   unknown type.  In particular, since the Accept header field does not\
   contain application/sdp, the response may not contain an SDP body.\
   The recipient of this request could respond with a 406 Not\
   Acceptable, with a Warning/399 indicating that a response cannot be\
   formulated in the formats offered in the Accept header field.  It is\
   also appropriate to respond with a 400 Bad Request, since all SIP\
   User-Agents (UAs) supporting INVITE are required to support\
   application/sdp.\
\
      Message Details : sdp01\
\
      INVITE sip:user@example.com SIP/2.0\
      To: sip:j_user@example.com\
      Contact: <sip:caller@host15.example.net>\
      From: sip:caller@example.net;tag=234\
      Max-Forwards: 5\
      Call-ID: sdp01.ndaksdj9342dasdd\
      Accept: text/nobodyKnowsThis\
      CSeq: 8 INVITE\
      Via: SIP/2.0/UDP 192.0.2.15;branch=z9hG4bKkdjuw\
      Content-Length: 150\
      Content-Type: application/sdp\
\
      v=0\
      o=mhandley 29739 7272939 IN IP4 192.0.2.5\
      s=-\
      c=IN IP4 192.0.2.5\
      t=0 0\
      m=audio 49217 RTP/AVP 0 12\
      m=video 3227 RTP/AVP 31\
      a=rtpmap:31 LPC\
\
3.4.  Backward Compatibility\
\
3.4.1.  INVITE with RFC 2543 Syntax\
\
   This is a legal message per RFC 2543 (and several bis versions) that\
   should be accepted by RFC 3261 elements that want to maintain\
   backwards compatibility.\
\
   o  There is no branch parameter at all on the Via header field value.\
\
   o  There is no From tag.\
\
\
\
\
\
Sparks, et al.               Informational                     [Page 44]\
\
RFC 4475               SIP Torture Test Messages                May 2006\
\
\
   o  There is no explicit Content-Length.  (The body is assumed to be\
      all octets in the datagram after the null-line.)\
\
   o  There is no Max-Forwards header field.\
\
      Message Details : inv2543\
\
      INVITE sip:UserB@example.com SIP/2.0\
      Via: SIP/2.0/UDP iftgw.example.com\
      From: <sip:+13035551111@ift.client.example.net;user=phone>\
      Record-Route: <sip:UserB@example.com;maddr=ss1.example.com>\
      To: sip:+16505552222@ss1.example.net;user=phone\
      Call-ID: inv2543.1717@ift.client.example.com\
      CSeq: 56 INVITE\
      Content-Type: application/sdp\
\
      v=0\
      o=mhandley 29739 7272939 IN IP4 192.0.2.5\
      s=-\
      c=IN IP4 192.0.2.5\
      t=0 0\
      m=audio 49217 RTP/AVP 0\
\
4.  Security Considerations\
\
   This document presents NON-NORMATIVE examples of SIP session\
   establishment.  The security considerations in [RFC3261] apply.\
\
   Parsers must carefully consider edge conditions and malicious input\
   as part of their design.  Attacks on many Internet systems use\
   crafted input to cause implementations to behave in undesirable ways.\
   Many of the messages in this document are designed to stress a parser\
   implementation at points traditionally used for such attacks.\
   However, this document does not attempt to be comprehensive.  It\
   should be considered a seed to stimulate thinking and planning, not\
   simply a set of tests to be passed.\
\
\
\
\
\
\
\
\
\
\
\
\
\
\
\
Sparks, et al.               Informational                     [Page 45]\
\
RFC 4475               SIP Torture Test Messages                May 2006\
\
\
5.  Acknowledgements\
\
   The final detailed review of this document was performed by Diego\
   Besprosvan, Vijay Gurbani, Shashi Kumar, Derek MacDonald, Gautham\
   Narasimhan, Nils Ohlmeier, Bob Penfield, Reinaldo Penno, Marc\
   Petit-Huguenin, Richard Sugarman, and Venkatesh Venkataramanan.\
\
   Earlier versions of this document were reviewed by Aseem Agarwal,\
   Rafi Assadi, Gonzalo Camarillo, Ben Campbell, Cullen Jennings, Vijay\
   Gurbani, Sunitha Kumar, Rohan Mahy, Jon Peterson, Marc\
   Petit-Huguenin, Vidhi Rastogi, Adam Roach, Bodgey Yin Shaohua, and\
   Tom Taylor.\
\
   Thanks to Cullen Jennings and Eric Rescorla for their contribution to\
   the multipart/mime sections of this document and their work\
   constructing S/MIME examples in [SIP-SEC].  Thanks to Neil Deason for\
   contributing several messages and to Kundan Singh for performing\
   parser validation of messages in earlier versions.\
\
   The following individuals provided significant comments during the\
   early phases of the development of this document: Jean-Francois Mule,\
   Hemant Agrawal, Henry Sinnreich, David Devanatham, Joe Pizzimenti,\
   Matt Cannon, John Hearty, the whole MCI IPOP Design team, Scott\
   Orton, Greg Osterhout, Pat Sollee, Doug Weisenberg, Danny Mistry,\
   Steve McKinnon, and Denise Ingram, Denise Caballero, Tom Redman, Ilya\
   Slain, Pat Sollee, John Truetken, and others from MCI, 3Com, Cisco,\
   Lucent, and Nortel.\
\
6.  Informative References\
\
   [RFC2822]  Resnick, P., "Internet Message Format", RFC 2822, April\
              2001.\
\
   [RFC3261]  Rosenberg, J., Schulzrinne, H., Camarillo, G., Johnston,\
              A., Peterson, J., Sparks, R., Handley, M., and E.\
              Schooler, "SIP:  Session Initiation Protocol", RFC 3261,\
              June 2002.\
\
   [RFC3264]  Rosenberg, J. and H. Schulzrinne, "An Offer/Answer Model\
              with Session Description Protocol (SDP)", RFC 3264, June\
              2002.\
\
   [RFC3986]  Berners-Lee, T., Fielding, R., and L. Masinter, "Uniform\
              Resource Identifier (URI): Generic Syntax", STD 66, RFC\
              3986, January 2005.\
\
   [SIP-SEC]  Jennings, C. and K. Ono, "Example call flows using SIP\
              security mechanisms", Work in Progress, July 2005.\
\
\
\
Sparks, et al.               Informational                     [Page 46]\
\
RFC 4475               SIP Torture Test Messages                May 2006\
\
\
Appendix A.  Bit-Exact Archive of Each Test Message\
\
   The following text block is an encoded, gzip-compressed TAR archive\
   of files that represent each of the example messages discussed in\
   Section 3.\
\
   To recover the compressed archive file intact, the text of this\
   document may be passed as input to the following Perl script (the\
   output should be redirected to a file or piped to "tar -xzvf -").\
\
   #!/usr/bin/perl\
   use strict;\
   my $bdata = "";\
   use MIME::Base64;\
   while(<>) {\
    if (/-- BEGIN MESSAGE ARCHIVE --/ .. /-- END MESSAGE ARCHIVE --/) {\
        if ( m/^\\s*[^\\s]+\\s*$/) {\
            $bdata = $bdata . $_;\
        }\
     }\
   }\
   print decode_base64($bdata);\
\
\
   Figure 58\
\
   Alternatively, the base-64 encoded block can be edited by hand to\
   remove document structure lines and fed as input to any base-64\
   decoding utility.\
\
\
\
\
\
\
\
\
\
\
\
\
\
\
\
\
\
\
\
\
\
\
Sparks, et al.               Informational                     [Page 47]\
\
RFC 4475               SIP Torture Test Messages                May 2006\
\
\
A.1.  Encoded Reference Messages\
\
   -- BEGIN MESSAGE ARCHIVE --\
   H4sIAEDwcEMCA+xdW2zc2Hm2nexNG6UN3LRF0QfaiKJdyxwdnkMOhyOPVrIt\
   27It22tdvHYTeM8MDzWc4ZAjkqORvK2bbIAAedmHtEHRdlvkoUCLFAjSlyLF\
   9rJPLYoWrTdAg6JFHwp0i+5D0SIoEAQFuj2HnAuH5GgoW3PxmgcazYU/b4f/\
   //3Xc04Rq9ipk1JGxe6xITVAW1YUvXc5K/W8syYheEygP0lIECWJ0gkSkMAx\
   DhwbQWs4LrY57phdcerYrjr96AZtb91L5/0paTdvbazevLHOOXo933CIvUT2\
   cK1ukIxlb3Prq7fmYQZMT23pON/+Nr958RZXthxXzLRpS1YtL4EsWCja2CyV\
   Cw+U8mWxeK2qVhoigkicnlrDe/wly25iW3XynEwPecmmO3GnzxPDOMstG/RQ\
   pkrs09w5diU4s50p0i1LgTMsLrh4uyAiJEI0PbVh0Z3vYNexzLPcRtmqYYfu\
   692Gm2l6v/fcyuL01AVsGPzqxTxXbPO8o2qAXp4JTdUBGChKA6IyKptmEwCl\
   pFZNQs+0XCqRupvncL1u6CXs6pY576h1erx1spPnkALpLSpcqyOnp4w8R29v\
   eurpeP60L/yHNkQAGCT/IsiG5R8KMJX/sco/lbiu/DNpi6NoizHbVqLi1Ysf\
   nsAiBEUYBgAUAymCQj9lYEYIochBEhiQ6BYXO1i1TM2CSBchqOwC7AAKKxqq\
   ILMtsbmnVVaHJP9U8Mkw1f8g+RcAFI+xf6IIBJRFVP7FbDbV/yNpqze2VjdW\
   jl78TeJ64g+pflWYwo5aAEHp9XiQqlGq22smlWEqsBAZFRHyvENUzax5VoQv\
   vwJVuQoSOf/S+xgnQdskxixpTk9dpKfMc5ds/SwHBO4qNjlIWZETsnkA6B+3\
   sr5Bz2iZLi5R7DkXuEd2fCkTuNNFn5CYLr+xXydxSNXafJ2Y226Z3oPk4c5u\
   gb5ZhVqZGj8G2eegIlNTQoYyvUGF3iC3ekvsAKM0PeUU+OmpUiG6wS0AhmS1\
   Am6ousXRLhdk7vbGrfnlrVscvSnItu3qKrE4BGF3ExKmp3DBdus1XM8jgbt+\
   68KzjIbPJv6bQ0X/BP6fgEL2n4gkKcX/Udt/sY5Trw/IWhBqS0l8wGYY/b3W\
   dQJpC7mBg71AXyl5rdcL9HeNu5WQC0jZnvKbIC313MNAf4+2Pi7f0yr/urkL\
   hHHGf2QEwvafDFAq/xNn/1Uyj2EBCkgUstSiF6CYjZiBvSLpcyIoY6A7poqr\
   jlrBDrUFWYwGO13/ra/l1/EhpYWFswtnzwYMuNNXLdKKLlUs0oMLC7TFmWhw\
   oFl3SAtO6GvCCeOy4Wiv7xLbGaf/B0QxqP8lT/5RNpX/idH/ckT/y3H6P6nq\
   79H8yxlP+Q/S+DtNYuk7dRLQ+xuZlupPrPI9TmdKXw4r/Y5uF56x4FCxhKmz\
   PFb7n4p+JP6Dsqn8j6S1tCcHAeBuXjtIpSq5kHwLCPqhncg+UJIygVd4PwcX\
   ic127Mqmx4UA5cScCCAQqMKnyl/DVVSBxG4SVXOW11Wtk3OROiZA1/wImya+\
   8SFQaUdtdyFCRtRGK0oFlTgLQEwU2OkGiLyDs/AQzAXxZfHwloKS62sqsE1p\
   vCdtR4P/ZM8drveXIP4jS2H7T4RCiv+Tl/+r3H+cFIAIiWuHDcFsEP59Juxx\
   /KanbpOdhm5T0DUtt6yb2+uNet2yXWejrDtn435c0d0yoSe6ZVt7+3xgd/aD\
   TpwWbXt/+6K1bO5Ht8XkCXs03Mb1dU6zDJWnQM5T7vEUySArOKxbJsWyLOrb\
   JUsda/4PSIIY8f/S+M9o7T8RKqKSlREQqDS6LrGZgHFFm+AqR6WKs0mJ6LtM\
   uvpbiCBs6UGk5Kg4WyQo6y2Gw45qaahRgQDRj6aG6BU06Keyhh1Eyl7gBzuK\
   3rX5kKiIIbvvXBxs+Q4jUrDpaHrL8jsXZ/r5hAqAFVM1q6zWJ0ZK+xh49GYj\
   Ft7TqP9LFLHtMed/5CwM+3/UaE/lf2Liv72aO/ekEWGF5fnpPwv2S7A3zG17\
   P5xhbyOIz7I9xkKT6JiihVpFCYLEven7qMbmWX5H5CGSIDp0Yl+h7THiwgcE\
   hocbGS5Rpsa18eZ/JCBE9b+cyv8o2u2Vy6vrGyu3PXmNFf6I/DjYbdjmYyV+\
   u5FfdrpQvLYds7lY1ba2K1XbXWtiYl+71g76xu8SBIY2L1PuEcBS9Drb4AC5\
   9m0HAIgdfk5QZEhZENK2tN0UghC00DCrptU0vZN8YqLDrT6D45R/MStH5B+m\
   +v9Zlf8cylEleTiZhwNlHsXJ/LlDCf3iJzAnpBYNm+yMNf4nICkbtv+ltP5r\
   UuQ/makf3doq1IKSUEEVBCODgHLTU6t5rsV/Pda8ojDfXzMNZFQhQqIAQ2q6\
   dbJwnW/X9u+Kev9oBZTiEMsrV+4TrqMX3PWWgkUkPf3Vvsbe7UkKZajTi+K6\
   qQN24c5SZJnKleJJ01KwlOQwhTIxnYBywK+3Hn5R85OXxHCJPZ800xVtxCkN\
   O/0zOP+P5DD+wzT+M/L4D305M2iZQeuMCALYFUSqqF6YkSWHzMgwDu08+2p1\
   BlLE2iX0jXZhiTjB47VisCgXwT15ekrPcz5/spEhQPFCwtVK1YTIMukXwKPA\
   sBDIBoaKScM+DHTjEzUHJPmnp7hOnGomeyFuKMgC/Z12xoI5kxVqpLBL34wG\
\
\
\
Sparks, et al.               Informational                     [Page 48]\
\
RFC 4475               SIP Torture Test Messages                May 2006\
\
\
   vXVpBokzSFg8ItTsC5ppaUDaDov/cMzx/2zU/6eSnOL/aOz/GVGmtvKMKPk+\
   gE22dce1sZ3p6w2cnrlHyVvF1DZxrIZd6jF2FzvD+wdSevCvQQQrWNUqPUVh\
   Pmsy0Dd3mhYS7R2IdCRWbJYbLJkGRKZtVE2H1YX1JugvDBwDCIEyoz1wTGIE\
   NYiCRJEL9kjssMWe4AE2dOwIfkowlBC8MJO9FCGFfnlYmDR6TOQRohDhkccf\
   aCebDcMYb/5fjMb/sun4/wnz/xmb8DMA8OxDP9e2L1Ersqco0J+/44DhwG2W\
   RAoEyFS13WpFxY5W3UFN0XLtHYBVR6OggHfVzpBgESk5Zv0d4PgPSvsFCnW6\
   okhvZSmy42IMVT/C6/nJjhfSzrYbtj7e8f9iJP4nS6n+H7X/Fw7gvXbbarik\
   MIMuhLBhBq0cydwASBQkIRc3JqzfqHsPP/rVBbRZ2XMWeWY3lCs8rhBUtHmK\
   DTtAyTV5DTeJXYY7fFk0pS58UKihyh8e7D3ylsa7ZcKXqRmTvOJvmMGz1A1M\
   25M13XQa2pj9PzEbGf8rpvnfseN/F+NbKOnVbQ3OKSgxOYWMx2cDQdFoDbs9\
   JA4qfZMISjo3yiD5d2vELY/V/oM99V9Z3/5L/b+RtFOUAYhNHFc3t/k1ygmW\
   6g2/k7JyTrl/Zu7NzIxuqoSosw89kBDuN8yG08BGZvP26sNXXIsvklNOwyav\
   flF3zFl3Tne/MF+y8YP9187OLyycyX9Rd+fK2CkIZ5tEt9VTZ+rY+ULTeqje\
   dy0r84pqEbYbr7uvLg0uP2lHdoSDyjczp2ay2TP3596cfdiKV51fuZ7/0gvc\
   jU36doy7yL79aisoddj7iQ1zuVaVmMLDN/0PcHbuvv8JnZk5leH9E9UaporN\
   UPBLo7vfYqUls7MP587cp8QzhdMffOXR9x790aM//+DtR9/74J0PvvHo+4/+\
   5LRnMN/3jvpQmJ17kx6ZzwSM37YcNy1bnbl3jT+VoT0wu8S+vvnw1VcWz+W/\
   NH/6y7/02q+8FZhGS4AQ5STuEDwQNtYhK08lexTTHQriVwhWiU3PPXNm7j7t\
   /vx/vfcXH/7e73/41Xc/+u33JncMzLNt/+1CSURjjf9lvfF/IfsvHf83avtv\
   k9p/55eS1QDqmrvdzPTL+M4JCCBJkgTalihppmToVPB7C+vo2Qr1smWSRTbU\
   r0SBivcCDq1jRK5moYZV1S44TjjO3o5AzAlZCbTr+IJkvafrAU2f+QVZkOOu\
   M1BTJGU7hu/Rzgnz+LP6HQl20i5ouOPO/wE5bP+J6fyfk+T/JZ0F84mGBeW8\
   gL94YG7AZ9feGaJUR9MrbBZvpHZrQSRRPKD8zbFqJNksof2FvVUZrFl2DbtR\
   40b0rJtznuTSnuHO1Uu1BsfGGBdOiyI6PU9/PDff3jy2529Y5vawC4AHyH82\
   K6NI/D/N/02Q/HtO1CrHirg4zDE6zsQ1wlkaR21/m9TIE75xddtiokHl6nTs\
   mN58lvZpTzG+UNgl9j5j36N87WKjQRbYJ+8k7C6H/So4ZXrn/omHcUtxL8/n\
   JNTpu0Hf7uhu+Ya1xS6AebQ+RuMafkDdQcO7HB+w2cUO8+doQTRUcpP4J0Kx\
   zYplz+MdCq8U/FMEzuDxyNH8a1+/99QN4jidWzjyDwHt3VY21Aq3Cf1xf/T/\
   2yynd2wFlGOVA6BjLGz6PcNfp5RH+eKZrOW5VsfzRy3SvP9ch3f8ehszeA/7\
   C6M4k3dPMTFAilAI9bppu1EK2EuxFaUQQhRx5wFhmuUIDVRCNKvR4/TOCMZo\
   Yo4jh+4p5npgNkwTcxwpRBN3PWKYJuY4oT7e4vJchCbUy7txNOF+5rjouUD4\
   OFEaQYk8rxiiXJQohkoe/OiFbAIaKQGNmIAGJaCBCWgSsLQABtMog0lyg0kS\
   dHKCPk7QxQl6OEEHJ+nfASQRr7I1cY5a6MR12o7mqIy9Ubz8W2rB9cCa2THY\
   lo+xZofxLBTlGO62O+wCwIHz/0Tmf5WEtP5vpP5//ERaR1Plp0BFiOQNg4X+\
   HR4UlgLB71aWcnC9iTTMZXqUIw7oI0FUEMzJYEKAwGg6qu7Ux5r/QzKL/7OB\
   3jKbDNqP/6X1XyNpR7P+ny9x52JQoDsf34Cq/zYjssIDXCypSxr1L/fjUnFZ\
   0GdiTgYKkb3iw/rpwn9d+R9//T8K5/8lANL5P8Yd/1/gDHswBPjCvacRXqFK\
   LJdD/ANFSzIrMPJnZo/k+6ReUPC4058MVLWIpbOll7zi/qZt+p9ySLSr3qCi\
   VvJPQNSkzIooQa2q0HfqIoiUgwwLYfSGxcGOxaQZFml7WvCfAaA7Vv9PhhH/\
   T07rP0aJ//H2X98ZYJ/IIczlBLEX41scqFXNHWr9UYwXEVAUrLKh37hJ0FKM\
   FSjkFJTLDZjvQxhkCSKlPcfrcFB+4sNHtZIx7vl/gCRnw/Vf6fwPE+X/HXoy\
   HTaVAkTJYMJiqzbEhY3YcKMAUPisqpVNZgJatl7GTU21MLJEW4IW0m2nu0IQ\
   ta+o+ddxEyOCGfFFsyBKJYUF3iV77nzdwLrJxHqDXjaZdTjT4pp4n3MtjuVD\
   adc0uRo29zmr5BLX4bBNOIetLuEQlREVCcd2zEyG+1nTnRp2S+VhgsDA+I8k\
   huRfgmn95yTGfx6rrhOJEpQOWv4lyIMVNvOgs6dqRtKp3NNgz5HIPxyf/Mve\
   +L8e+59+SeV/FO3Gyp21lY0rNy9OBgLAAQjQ11IPGeoHI0X/yf8GZ4TZTIWH\
   N+njrPmJiNHUKFMPewG4AfIPRYH5/wjK9Mkj4M3/JKX6fzRtbWV9ffmyHwCu\
   Nmp61Yqs/hvvAQhQpowMvAiqHI6g8mpOlkTEiypWCciqoKgWBYEQXuDbmxZs\
\
\
\
Sparks, et al.               Informational                     [Page 49]\
\
RFC 4475               SIP Torture Test Messages                May 2006\
\
\
   VvAdlxIKjgILniUHqGCvqlQ+dXc/z9lSrWmT6439i7fvntfnwYZ+q7ni3EX2\
   ypZTnb8M7+yVtze2hFuX5PKVxvXVa+Duna1r98rXdpW1Sm6TvLFTXdsqmls7\
   SL5wcS4noO3du5XS+U18z9x+vfZGSblz4976xRuXLzxYntPuGMrayuaVO6v3\
   LOECuUqK6t35N4zta2QDg5vG7g6wXRm8LlX0da24s3a19vollxB9d7NcXbtz\
   d3O5EAYuzWho2v5Sbx8uBpaqij6KxZ4Rdq0DRLJsUCsCtVRSAtiKVEXMSVgF\
   JVHJSUpx6V5tT7hXuyddvyOU7+6DvRu65BThjXJxOZPppt1bjBHARJstqEVs\
   fsUsWapubrO1vExs74dhs9YwXJ3BynxN3yPqQtFiQ5/t/YKMlVKRlAAsEaJl\
   2cjhi5g96XXsnqUeG3ez5LJ1aCUOiHlRzEtZ7vLaxvQUGwnIL2/TE3gcqNfq\
   rD/mvZQ690qpYTvEeTXGe5MQQ2qej562v1eX4Ganp64Qw7CSHDmoQDxvkHdc\
   m7DVQxKdB7x9/PbzL535+pWv/3j6+Asnvv328Qv0p9dOHD8uvAReeP65uc9+\
   6sQvgJe7JMeFt49zlOQXKQn4ZVAXXgYvPf+pzU8/f/LE5rpwEnyOfXnxJOMN\
   XbNsU8fC58BPsR9fOPniOja5q9RJFT4LPsN+mjr5HOU03RVeBbPs+8snuXX2\
   ndsgjstdILara+zmCLfccMvUH3f3T7x4/FvHdk6g4ye7lzfdubzjx5879umv\
   fuWd/9F+cuW/b/M/+PA33vmdb33nox/93+e/rd3dKX7zP/7pzB/8ozRV/ruP\
   v3vuz+Y+/tnGv/yD+s7dwg8vv/KjIvfjj5bd30XTv/X5//zDf/61Dz5z/qcz\
   b9nf+MG77//1dzP/+1fv//1Pfm5+4cTDm+/P/utG7d/++Dv59xa1v/2bL//w\
   L6997Ws/8+73//3jn+d//eaHb5E//c1Hz8U9OJ5/Vr0DT1jHq/8FCILjv0Rf\
   /6frP40l/0s1SR2b+wnHf0JpkN3dtnfjV1uIrQjxx1t3Tf6Ok9BiVSXHlolc\
   CljSrV2UxPvAA5yWTk6bpafZIgT9Y5jtLZEIZpL8tzcTJptnI1khqnjQtHjZ\
   0GOIZNQP6bHAvkVs8KgnVErDMmNtZskYcvYnQfynZ/5PD/9BWv83HvxPsP4n\
   ZFj0ZPEgL7WDgllgxoc9w/qh4KWQbEmETdQpBwYJyoFRkol9e69MQk+W6OUf\
   Z9VP5p/0qRRGIxsqYFrUIXEsc6zr/0EYyP/IXv0HSuV/JK29/jftf+6J1/bu\
   MBOmUsxW9tbZ7PyKAiGbx7u7kne6ivfk6H9rlxhOaaz1/yKUQvKf1v+PPP9r\
   4XqmSEg9Pz/fFXqURwDAoxkGlItU+qIe6PD50K/0pYcHOxRhzKZf+Fs1uqt0\
   IH8JgT5jANpjMJUklV9iOifhTsNyi3i863/IohS2/+V0/c8Jsv+9+X/W7Ax3\
   NcOxaLyvRaOm/2ICHFBQzCKXQnAkUJslPTfgoLF9SthoT7rqpaTkJSCBBLCQ\
   uNATjmHly6PIEdtkGzeGnABONv97r/4X0/k/R9KGvP5vTkZQKFcgEmDuoJVt\
   O2zYEwNoizTFjL5r+jKF3w1O9vH9WxmqB54I57kb1k2TXDOtprNR1p31UplN\
   QWbV8U6D8FQOcIEVaEak/BNpGtCOL2K15I5X/lHY/wdp/mfS5P8g6Y+VfUXJ\
   IQQPHPTb4b4qEiXs2AbS1OLukgD8sohuNcJBC3ojKSPkKDViL9R3QF9oDfGD\
   Vzuir0zvikef0DJS+gTYuknjlX8pG43/pfWfT7v85waJvs94IdEPZ3X/v72j\
   2W3bBt8L9B2IALsEcUqRki05c9Fi2LB2a7I169JDgUKxKFv+oRxSspqctp4H\
   7F2G9bjtFZI3Gj9RdiXZlpN2tZNVbFLHlCjJ9Pf/+x+29nu2wtS4DvXvQBu/\
   Dx5SKVSu+LQtgNfq/9RckP9Jjf+3BP+XN2AhVQY2ahLp+eFqs33eVlBh/Seg\
   jZNBfx4ITpu2Q01IIFUKogMxw5TkCMOcuMyhmtAQTzxn6vLRGU24GHGWhP7A\
   lU4cLMomFKvP+/WbSSBYapTYwFjtmijuMJQQRwdMP1uH2Jg4LctpNimxDesj\
   zJh6p0a9beJ/U+d/ENLEoCim8n9t/9us/8/CFB0zMQ26DL3g7tQNRu7piH0Q\
   +l9cvPEC6Ngtk8Xyh2rptanCQlxVRhaYK72BzwbJ3EBA0mxRm5qtFqHYhEQC\
   I5//WSQMCtx56EqGQx+STfqcnIV+6MIb4rLEh2sJ6EoSifPGYz9iQt3CdCgm\
   NrXVTsErvIX7OLaSc05cwdPgXcNWtw2nTESxYGjnCUc/iLCnUFbu3E5fg/Qm\
   W8//blkL8T+E1vr/7bL/p0a+14tKwOraCeXY0GuUBKosBqRBNTMNQnCQp8iA\
   d//e426XTaIsjp+Hp6F3Prft3cApYFjVOWGFog63pQfQRzsCJBsHW67/ha1W\
   Tv5vZvX/mjX+b2KU878P1IfsxF+YOIecNycKK1E9FD0dDUCJSariAWZwudQf\
   YL/n7DPkL6HgXmFiMuzKVmMcjNkeiNF6lNKU9nITMuhxNZM7VzFwt8fUAXXl\
   3BtfuL0qknL789EjJj91+6/19r98/ReN/6RV+/82zf+VZMwfKdU4HAdZesMR\
   UohVntW4LdzRpF9E+mfuy4Z/JE7c596xgnDczDv4UjgrIHPe1Pfy/OLivEHU\
   aYpnI/WjBH/E4/EpE2olRzpCQJ9F23Nenk4UFHX1FMzVorgfhuhUfbXqa4On\
   DkN4I9KXJUzdvi5Pj3Sf1E6auHH37X8RJCBCJq7cYv2HZquE/5ZV2/+3w/8/\
\
\
\
Sparks, et al.               Informational                     [Page 50]\
\
RFC 4475               SIP Torture Test Messages                May 2006\
\
\
   rP7vR1X+RTkYHAaDvukOPe6eDYYJ4550pQ+MfwWfv1ZN4PVl4EqLjr/6Sa0i\
   VatGrhx4fb9sH/n+GEW0Yh1xbBxzDz5R8TEPvzs8OjlEkVmxWKk72KeMLzHK\
   VLo/sOsEns8ZWyJ6RCKR2+b/Fi7jv0lxjf8bx3/BxmHEGmo/esuFfoQq+7Gv\
   gHhQ1bGT9wWsvFHR/DcKFUlpCCbDWHTZMsLimMTBdr7aQQrPYdCNqelYNoQQ\
   Mx8iiPsCGpqLtYSEUNvJBxcv72Xy/4kYjvlQdseflgKslf9NWsb/Zo3/m8X/\
   kt1Mx8S1ozCCpnk6NK6rAX8T2QAZVPI6G2AT+D8mW8Z/Ssr4b5Fa/78l/n/A\
   8kCe8raSXWnLIXaLzrl0P4ogYShJkv1lYr9CzDJWp7CWqv/980mfcTdiXqNc\
   xvE9MzYdnHfwL3Lj1QUnjOtEAn4JzcHaT8M+f308DqL+w8+tWmTMt57/a2Cj\
   7P+zDFrXf9vImEn2BGPUQWR3l6JdZO3uEnT51+Xf6OrXq7fq5fLPy3eXf1z9\
   DnOlqau3V7+hBrr85+qX2bHLd1U2cccu4aRBiemQIqHIgBKaAQ2B6Q/pgDCR\
   MM+Xj48rUolXBiMahm43skJqYV6sXZAEwhMWXX7XSwlaFsbj2AsZxjdLE3Ls\
   lXlCcOj2tRSsxx0aiQz4dLvxH0bLMsrxH0oArOn/hv0/02DKhr1H3b4biIbH\
   RbegNGXdvtPe3Dnh8Ai1799bvxwdIIQUgQVnakcRMMOGf5Ty+/d8AZ1GUBvt\
   PEXPQ8n4KRM99OrVq52dzPuqs009AQcfLcREwn9w5Q6CIl8Dz17jidIQv8QJ\
   VaT66SOlsR5dmVaewdiBW+XiSLK20gg9UCen24GA1Wm38VwOnXE76mCZiZ8S\
   Nu2QJd+4vDdi3rfM9SDEDCHOEl/PoayXLgKtO+Cxmlk8mLWq1+tPlPj6gscy\
   dkc/w+E2OjjY21O/B2t5l664qm6W7rTUYYCy8PWPxAwCEnWfjm42P+sAz0Pd\
   qf1h2oZ9tiepwfABAh0chpwEwO4KUJF9fXqHADIQyoQCJxgObITABz/fYn1F\
   9SfIE+kGG017n1jWvuLucK3sQh21aBaJDBF6igO2d36MQ6VqIBmJgCvw2gHw\
   WglY6lJqtzWsd2ZhAGom/ZT6mSXYQzx9ygE6U8+O9ym9MXtfWQPI3Axrv2AK\
   /fwt6/8EL9r/av3/Dvn/qix9vb70TCNHgDOQG4Apb+TzMQnJyKTCirE29xVM\
   e5QYFZ69a/V4AitCULYd4Lr0Rz3qUY/PfPwLcaRGXQDwAAA=\
   -- END MESSAGE ARCHIVE --\
\
\
\
\
\
\
\
\
\
\
\
\
\
\
\
\
\
\
\
\
\
\
\
\
\
\
\
\
Sparks, et al.               Informational                     [Page 51]\
\
RFC 4475               SIP Torture Test Messages                May 2006\
\
\
Authors' Addresses\
\
   Robert J. Sparks (editor)\
   Estacado Systems\
\
   EMail: RjS@estacado.net\
\
\
   Alan Hawrylyshen\
   Ditech Networks\
   200 - 1167 Kensington Cr. NW\
   Calgary, Alberta  T2N 1X7\
   Canada\
\
   Phone : +1.403.806.3366\
   EMail : ahawrylyshen@ditechcom.com\
\
\
   Alan Johnston\
   Avaya\
   St. Louis, MO 63124\
\
   EMail: alan@sipstation.com\
\
\
   Jonathan Rosenberg\
   Cisco Systems\
   600 Lanidex Plaza\
   Parsippany, NJ  07052\
\
   Phone: +1 973 952 5000\
   EMail: jdrosen@cisco.com\
   URI:   http://www.jdrosen.net\
\
\
   Henning Schulzrinne\
   Columbia University\
   Department of Computer Science\
   450 Computer Science Building\
   New York, NY  10027\
   US\
\
   Phone: +1 212 939 7042\
   EMail: hgs@cs.columbia.edu\
   URI:   http://www.cs.columbia.edu\
\
\
\
\
\
\
Sparks, et al.               Informational                     [Page 52]\
\
RFC 4475               SIP Torture Test Messages                May 2006\
\
\
Full Copyright Statement\
\
   Copyright (C) The Internet Society (2006).\
\
   This document is subject to the rights, licenses and restrictions\
   contained in BCP 78, and except as set forth therein, the authors\
   retain all their rights.\
\
   This document and the information contained herein are provided on an\
   "AS IS" basis and THE CONTRIBUTOR, THE ORGANIZATION HE/SHE REPRESENTS\
   OR IS SPONSORED BY (IF ANY), THE INTERNET SOCIETY AND THE INTERNET\
   ENGINEERING TASK FORCE DISCLAIM ALL WARRANTIES, EXPRESS OR IMPLIED,\
   INCLUDING BUT NOT LIMITED TO ANY WARRANTY THAT THE USE OF THE\
   INFORMATION HEREIN WILL NOT INFRINGE ANY RIGHTS OR ANY IMPLIED\
   WARRANTIES OF MERCHANTABILITY OR FITNESS FOR A PARTICULAR PURPOSE.\
\
Intellectual Property\
\
   The IETF takes no position regarding the validity or scope of any\
   Intellectual Property Rights or other rights that might be claimed to\
   pertain to the implementation or use of the technology described in\
   this document or the extent to which any license under such rights\
   might or might not be available; nor does it represent that it has\
   made any independent effort to identify any such rights.  Information\
   on the procedures with respect to rights in RFC documents can be\
   found in BCP 78 and BCP 79.\
\
   Copies of IPR disclosures made to the IETF Secretariat and any\
   assurances of licenses to be made available, or the result of an\
   attempt made to obtain a general license or permission for the use of\
   such proprietary rights by implementers or users of this\
   specification can be obtained from the IETF on-line IPR repository at\
   http://www.ietf.org/ipr.\
\
   The IETF invites any interested party to bring to its attention any\
   copyrights, patents or patent applications, or other proprietary\
   rights that may cover technology that may be required to implement\
   this standard.  Please address the information to the IETF at\
   ietf-ipr@ietf.org.\
\
Acknowledgement\
\
   Funding for the RFC Editor function is provided by the IETF\
   Administrative Support Activity (IASA).\
\
\
\
\
\
\
\
Sparks, et al.               Informational                     [Page 53]\
\

doc 12
  field 0
    name titolo
    type string
    value rfc4472.txt
  field 1
    name contenuto
    type string
    value \
\
\
\
\
\
Network Working Group                                          A. Durand\
Request for Comments: 4472                                       Comcast\
Category: Informational                                         J. Ihren\
                                                              Autonomica\
                                                               P. Savola\
                                                               CSC/FUNET\
                                                              April 2006\
\
\
          Operational Considerations and Issues with IPv6 DNS\
\
Status of This Memo\
\
   This memo provides information for the Internet community.  It does\
   not specify an Internet standard of any kind.  Distribution of this\
   memo is unlimited.\
\
Copyright Notice\
\
   Copyright (C) The Internet Society (2006).\
\
Abstract\
\
   This memo presents operational considerations and issues with IPv6\
   Domain Name System (DNS), including a summary of special IPv6\
   addresses, documentation of known DNS implementation misbehavior,\
   recommendations and considerations on how to perform DNS naming for\
   service provisioning and for DNS resolver IPv6 support,\
   considerations for DNS updates for both the forward and reverse\
   trees, and miscellaneous issues.  This memo is aimed to include a\
   summary of information about IPv6 DNS considerations for those who\
   have experience with IPv4 DNS.\
\
Table of Contents\
\
   1. Introduction ....................................................3\
      1.1. Representing IPv6 Addresses in DNS Records .................3\
      1.2. Independence of DNS Transport and DNS Records ..............4\
      1.3. Avoiding IPv4/IPv6 Name Space Fragmentation ................4\
      1.4. Query Type '*' and A/AAAA Records ..........................4\
   2. DNS Considerations about Special IPv6 Addresses .................5\
      2.1. Limited-Scope Addresses ....................................5\
      2.2. Temporary Addresses ........................................5\
      2.3. 6to4 Addresses .............................................5\
      2.4. Other Transition Mechanisms ................................5\
   3. Observed DNS Implementation Misbehavior .........................6\
      3.1. Misbehavior of DNS Servers and Load-balancers ..............6\
      3.2. Misbehavior of DNS Resolvers ...............................6\
\
\
\
Durand, et al.               Informational                      [Page 1]\
\
RFC 4472              Considerations with IPv6 DNS            April 2006\
\
\
   4. Recommendations for Service Provisioning Using DNS ..............7\
      4.1. Use of Service Names instead of Node Names .................7\
      4.2. Separate vs. the Same Service Names for IPv4 and IPv6 ......8\
      4.3. Adding the Records Only When Fully IPv6-enabled ............8\
      4.4. The Use of TTL for IPv4 and IPv6 RRs .......................9\
           4.4.1. TTL with Courtesy Additional Data ...................9\
           4.4.2. TTL with Critical Additional Data ..................10\
      4.5. IPv6 Transport Guidelines for DNS Servers .................10\
   5. Recommendations for DNS Resolver IPv6 Support ..................10\
      5.1. DNS Lookups May Query IPv6 Records Prematurely ............10\
      5.2. Obtaining a List of DNS Recursive Resolvers ...............12\
      5.3. IPv6 Transport Guidelines for Resolvers ...................12\
   6. Considerations about Forward DNS Updating ......................13\
      6.1. Manual or Custom DNS Updates ..............................13\
      6.2. Dynamic DNS ...............................................13\
   7. Considerations about Reverse DNS Updating ......................14\
      7.1. Applicability of Reverse DNS ..............................14\
      7.2. Manual or Custom DNS Updates ..............................15\
      7.3. DDNS with Stateless Address Autoconfiguration .............16\
      7.4. DDNS with DHCP ............................................17\
      7.5. DDNS with Dynamic Prefix Delegation .......................17\
   8. Miscellaneous DNS Considerations ...............................18\
      8.1. NAT-PT with DNS-ALG .......................................18\
      8.2. Renumbering Procedures and Applications' Use of DNS .......18\
   9. Acknowledgements ...............................................19\
   10. Security Considerations .......................................19\
   11. References ....................................................20\
      11.1. Normative References .....................................20\
      11.2. Informative References ...................................22\
   Appendix A. Unique Local Addressing Considerations for DNS ........24\
   Appendix B. Behavior of Additional Data in IPv4/IPv6\
               Environments ..........................................24\
      B.1. Description of Additional Data Scenarios ..................24\
      B.2. Which Additional Data to Keep, If Any? ....................26\
      B.3. Discussion of the Potential Problems ......................27\
\
\
\
\
\
\
\
\
\
\
\
\
\
\
\
\
Durand, et al.               Informational                      [Page 2]\
\
RFC 4472              Considerations with IPv6 DNS            April 2006\
\
\
1.  Introduction\
\
   This memo presents operational considerations and issues with IPv6\
   DNS; it is meant to be an extensive summary and a list of pointers\
   for more information about IPv6 DNS considerations for those with\
   experience with IPv4 DNS.\
\
   The purpose of this document is to give information about various\
   issues and considerations related to DNS operations with IPv6; it is\
   not meant to be a normative specification or standard for IPv6 DNS.\
\
   The first section gives a brief overview of how IPv6 addresses and\
   names are represented in the DNS, how transport protocols and\
   resource records (don't) relate, and what IPv4/IPv6 name space\
   fragmentation means and how to avoid it; all of these are described\
   at more length in other documents.\
\
   The second section summarizes the special IPv6 address types and how\
   they relate to DNS.  The third section describes observed DNS\
   implementation misbehaviors that have a varying effect on the use of\
   IPv6 records with DNS.  The fourth section lists recommendations and\
   considerations for provisioning services with DNS.  The fifth section\
   in turn looks at recommendations and considerations about providing\
   IPv6 support in the resolvers.  The sixth and seventh sections\
   describe considerations with forward and reverse DNS updates,\
   respectively.  The eighth section introduces several miscellaneous\
   IPv6 issues relating to DNS for which no better place has been found\
   in this memo.  Appendix A looks briefly at the requirements for\
   unique local addressing.  Appendix B discusses additional data.\
\
1.1.  Representing IPv6 Addresses in DNS Records\
\
   In the forward zones, IPv6 addresses are represented using AAAA\
   records.  In the reverse zones, IPv6 address are represented using\
   PTR records in the nibble format under the ip6.arpa. tree.  See\
   [RFC3596] for more about IPv6 DNS usage, and [RFC3363] or [RFC3152]\
   for background information.\
\
   In particular, one should note that the use of A6 records in the\
   forward tree or Bitlabels in the reverse tree is not recommended\
   [RFC3363].  Using DNAME records is not recommended in the reverse\
   tree in conjunction with A6 records; the document did not mean to\
   take a stance on any other use of DNAME records [RFC3364].\
\
\
\
\
\
\
\
\
Durand, et al.               Informational                      [Page 3]\
\
RFC 4472              Considerations with IPv6 DNS            April 2006\
\
\
1.2.  Independence of DNS Transport and DNS Records\
\
   DNS has been designed to present a single, globally unique name space\
   [RFC2826].  This property should be maintained, as described here and\
   in Section 1.3.\
\
   The IP version used to transport the DNS queries and responses is\
   independent of the records being queried: AAAA records can be queried\
   over IPv4, and A records over IPv6.  The DNS servers must not make\
   any assumptions about what data to return for Answer and Authority\
   sections based on the underlying transport used in a query.\
\
   However, there is some debate whether the addresses in Additional\
   section could be selected or filtered using hints obtained from which\
   transport was being used; this has some obvious problems because in\
   many cases the transport protocol does not correlate with the\
   requests, and because a "bad" answer is in a way worse than no answer\
   at all (consider the case where the client is led to believe that a\
   name received in the additional record does not have any AAAA records\
   at all).\
\
   As stated in [RFC3596]:\
\
      The IP protocol version used for querying resource records is\
      independent of the protocol version of the resource records; e.g.,\
      IPv4 transport can be used to query IPv6 records and vice versa.\
\
1.3.  Avoiding IPv4/IPv6 Name Space Fragmentation\
\
   To avoid the DNS name space from fragmenting into parts where some\
   parts of DNS are only visible using IPv4 (or IPv6) transport, the\
   recommendation is to always keep at least one authoritative server\
   IPv4-enabled, and to ensure that recursive DNS servers support IPv4.\
   See DNS IPv6 transport guidelines [RFC3901] for more information.\
\
1.4.  Query Type '*' and A/AAAA Records\
\
   QTYPE=* is typically only used for debugging or management purposes;\
   it is worth keeping in mind that QTYPE=* ("ANY" queries) only return\
   any available RRsets, not *all* the RRsets, because the caches do not\
   necessarily have all the RRsets and have no way of guaranteeing that\
   they have all the RRsets.  Therefore, to get both A and AAAA records\
   reliably, two separate queries must be made.\
\
\
\
\
\
\
\
\
Durand, et al.               Informational                      [Page 4]\
\
RFC 4472              Considerations with IPv6 DNS            April 2006\
\
\
2.  DNS Considerations about Special IPv6 Addresses\
\
   There are a couple of IPv6 address types that are somewhat special;\
   these are considered here.\
\
2.1.  Limited-Scope Addresses\
\
   The IPv6 addressing architecture [RFC4291] includes two kinds of\
   local-use addresses: link-local (fe80::/10) and site-local\
   (fec0::/10).  The site-local addresses have been deprecated [RFC3879]\
   but are discussed with unique local addresses in Appendix A.\
\
   Link-local addresses should never be published in DNS (whether in\
   forward or reverse tree), because they have only local (to the\
   connected link) significance [WIP-DC2005].\
\
2.2.  Temporary Addresses\
\
   Temporary addresses defined in RFC 3041 [RFC3041] (sometimes called\
   "privacy addresses") use a random number as the interface identifier.\
   Having DNS AAAA records that are updated to always contain the\
   current value of a node's temporary address would defeat the purpose\
   of the mechanism and is not recommended.  However, it would still be\
   possible to return a non-identifiable name (e.g., the IPv6 address in\
   hexadecimal format), as described in [RFC3041].\
\
2.3.  6to4 Addresses\
\
   6to4 [RFC3056] specifies an automatic tunneling mechanism that maps a\
   public IPv4 address V4ADDR to an IPv6 prefix 2002:V4ADDR::/48.\
\
   If the reverse DNS population would be desirable (see Section 7.1 for\
   applicability), there are a number of possible ways to do so.\
\
   [WIP-H2005] aims to design an autonomous reverse-delegation system\
   that anyone being capable of communicating using a specific 6to4\
   address would be able to set up a reverse delegation to the\
   corresponding 6to4 prefix.  This could be deployed by, e.g., Regional\
   Internet Registries (RIRs).  This is a practical solution, but may\
   have some scalability concerns.\
\
2.4.  Other Transition Mechanisms\
\
   6to4 is mentioned as a case of an IPv6 transition mechanism requiring\
   special considerations.  In general, mechanisms that include a\
   special prefix may need a custom solution; otherwise, for example,\
   when IPv4 address is embedded as the suffix or not embedded at all,\
   special solutions are likely not needed.\
\
\
\
Durand, et al.               Informational                      [Page 5]\
\
RFC 4472              Considerations with IPv6 DNS            April 2006\
\
\
   Note that it does not seem feasible to provide reverse DNS with\
   another automatic tunneling mechanism, Teredo [RFC4380]; this is\
   because the IPv6 address is based on the IPv4 address and UDP port of\
   the current Network Address Translation (NAT) mapping, which is\
   likely to be relatively short-lived.\
\
3.  Observed DNS Implementation Misbehavior\
\
   Several classes of misbehavior in DNS servers, load-balancers, and\
   resolvers have been observed.  Most of these are rather generic, not\
   only applicable to IPv6 -- but in some cases, the consequences of\
   this misbehavior are extremely severe in IPv6 environments and\
   deserve to be mentioned.\
\
3.1.  Misbehavior of DNS Servers and Load-balancers\
\
   There are several classes of misbehavior in certain DNS servers and\
   load-balancers that have been noticed and documented [RFC4074]: some\
   implementations silently drop queries for unimplemented DNS records\
   types, or provide wrong answers to such queries (instead of a proper\
   negative reply).  While typically these issues are not limited to\
   AAAA records, the problems are aggravated by the fact that AAAA\
   records are being queried instead of (mainly) A records.\
\
   The problems are serious because when looking up a DNS name, typical\
   getaddrinfo() implementations, with AF_UNSPEC hint given, first try\
   to query the AAAA records of the name, and after receiving a\
   response, query the A records.  This is done in a serial fashion --\
   if the first query is never responded to (instead of properly\
   returning a negative answer), significant time-outs will occur.\
\
   In consequence, this is an enormous problem for IPv6 deployments, and\
   in some cases, IPv6 support in the software has even been disabled\
   due to these problems.\
\
   The solution is to fix or retire those misbehaving implementations,\
   but that is likely not going to be effective.  There are some\
   possible ways to mitigate the problem, e.g., by performing the\
   lookups somewhat in parallel and reducing the time-out as long as at\
   least one answer has been received, but such methods remain to be\
   investigated; slightly more on this is included in Section 5.\
\
3.2.  Misbehavior of DNS Resolvers\
\
   Several classes of misbehavior have also been noticed in DNS\
   resolvers [WIP-LB2005].  However, these do not seem to directly\
   impair IPv6 use, and are only referred to for completeness.\
\
\
\
\
Durand, et al.               Informational                      [Page 6]\
\
RFC 4472              Considerations with IPv6 DNS            April 2006\
\
\
4.  Recommendations for Service Provisioning Using DNS\
\
   When names are added in the DNS to facilitate a service, there are\
   several general guidelines to consider to be able to do it as\
   smoothly as possible.\
\
4.1.  Use of Service Names instead of Node Names\
\
   It makes sense to keep information about separate services logically\
   separate in the DNS by using a different DNS hostname for each\
   service.  There are several reasons for doing this, for example:\
\
   o  It allows more flexibility and ease for migration of (only a part\
      of) services from one node to another,\
\
   o  It allows configuring different properties (e.g., Time to Live\
      (TTL)) for each service, and\
\
   o  It allows deciding separately for each service whether or not to\
      publish the IPv6 addresses (in cases where some services are more\
      IPv6-ready than others).\
\
   Using SRV records [RFC2782] would avoid these problems.\
   Unfortunately, those are not sufficiently widely used to be\
   applicable in most cases.  Hence an operation technique is to use\
   service names instead of node names (or "hostnames").  This\
   operational technique is not specific to IPv6, but required to\
   understand the considerations described in Section 4.2 and\
   Section 4.3.\
\
   For example, assume a node named "pobox.example.com" provides both\
   SMTP and IMAP service.  Instead of configuring the MX records to\
   point at "pobox.example.com", and configuring the mail clients to\
   look up the mail via IMAP from "pobox.example.com", one could use,\
   e.g., "smtp.example.com" for SMTP (for both message submission and\
   mail relaying between SMTP servers) and "imap.example.com" for IMAP.\
   Note that in the specific case of SMTP relaying, the server itself\
   must typically also be configured to know all its names to ensure\
   that loops do not occur.  DNS can provide a layer of indirection\
   between service names and where the service actually is, and using\
   which addresses.  (Obviously, when wanting to reach a specific node,\
   one should use the hostname rather than a service name.)\
\
\
\
\
\
\
\
\
\
Durand, et al.               Informational                      [Page 7]\
\
RFC 4472              Considerations with IPv6 DNS            April 2006\
\
\
4.2.  Separate vs. the Same Service Names for IPv4 and IPv6\
\
   The service naming can be achieved in basically two ways: when a\
   service is named "service.example.com" for IPv4, the IPv6-enabled\
   service could either be added to "service.example.com" or added\
   separately under a different name, e.g., in a sub-domain like\
   "service.ipv6.example.com".\
\
   These two methods have different characteristics.  Using a different\
   name allows for easier service piloting, minimizing the disturbance\
   to the "regular" users of IPv4 service; however, the service would\
   not be used transparently, without the user/application explicitly\
   finding it and asking for it -- which would be a disadvantage in most\
   cases.  When the different name is under a sub-domain, if the\
   services are deployed within a restricted network (e.g., inside an\
   enterprise), it's possible to prefer them transparently, at least to\
   a degree, by modifying the DNS search path; however, this is a\
   suboptimal solution.  Using the same service name is the "long-term"\
   solution, but may degrade performance for those clients whose IPv6\
   performance is lower than IPv4, or does not work as well (see\
   Section 4.3 for more).\
\
   In most cases, it makes sense to pilot or test a service using\
   separate service names, and move to the use of the same name when\
   confident enough that the service level will not degrade for the\
   users unaware of IPv6.\
\
4.3.  Adding the Records Only When Fully IPv6-enabled\
\
   The recommendation is that AAAA records for a service should not be\
   added to the DNS until all of following are true:\
\
   1.  The address is assigned to the interface on the node.\
\
   2.  The address is configured on the interface.\
\
   3.  The interface is on a link that is connected to the IPv6\
       infrastructure.\
\
   In addition, if the AAAA record is added for the node, instead of\
   service as recommended, all the services of the node should be IPv6-\
   enabled prior to adding the resource record.\
\
   For example, if an IPv6 node is isolated from an IPv6 perspective\
   (e.g., it is not connected to IPv6 Internet) constraint #3 would mean\
   that it should not have an address in the DNS.\
\
\
\
\
\
Durand, et al.               Informational                      [Page 8]\
\
RFC 4472              Considerations with IPv6 DNS            April 2006\
\
\
   Consider the case of two dual-stack nodes, which both are IPv6-\
   enabled, but the server does not have (global) IPv6 connectivity.  As\
   the client looks up the server's name, only A records are returned\
   (if the recommendations above are followed), and no IPv6\
   communication, which would have been unsuccessful, is even attempted.\
\
   The issues are not always so black-and-white.  Usually, it's\
   important that the service offered using both protocols is of roughly\
   equal quality, using the appropriate metrics for the service (e.g.,\
   latency, throughput, low packet loss, general reliability, etc.).\
   This is typically very important especially for interactive or real-\
   time services.  In many cases, the quality of IPv6 connectivity may\
   not yet be equal to that of IPv4, at least globally; this has to be\
   taken into consideration when enabling services.\
\
4.4.  The Use of TTL for IPv4 and IPv6 RRs\
\
   The behavior of DNS caching when different TTL values are used for\
   different RRsets of the same name calls for explicit discussion.  For\
   example, let's consider two unrelated zone fragments:\
\
      example.com.        300    IN    MX     foo.example.com.\
      foo.example.com.    300    IN    A      192.0.2.1\
      foo.example.com.    100    IN    AAAA   2001:db8::1\
\
   ...\
\
      child.example.com.    300  IN    NS     ns.child.example.com.\
      ns.child.example.com. 300  IN    A      192.0.2.1\
      ns.child.example.com. 100  IN    AAAA   2001:db8::1\
\
   In the former case, we have "courtesy" additional data; in the\
   latter, we have "critical" additional data.  See more extensive\
   background discussion of additional data handling in Appendix B.\
\
4.4.1.  TTL with Courtesy Additional Data\
\
   When a caching resolver asks for the MX record of example.com, it\
   gets back "foo.example.com".  It may also get back either one or both\
   of the A and AAAA records in the additional section.  The resolver\
   must explicitly query for both A and AAAA records [RFC2821].\
\
   After 100 seconds, the AAAA record is removed from the cache(s)\
   because its TTL expired.  It could be argued to be useful for the\
   caching resolvers to discard the A record when the shorter TTL (in\
   this case, for the AAAA record) expires; this would avoid the\
   situation where there would be a window of 200 seconds when\
   incomplete information is returned from the cache.  Further argument\
\
\
\
Durand, et al.               Informational                      [Page 9]\
\
RFC 4472              Considerations with IPv6 DNS            April 2006\
\
\
   for discarding is that in the normal operation, the TTL values are so\
   high that very likely the incurred additional queries would not be\
   noticeable, compared to the obtained performance optimization.  The\
   behavior in this scenario is unspecified.\
\
4.4.2.  TTL with Critical Additional Data\
\
   The difference to courtesy additional data is that the A/AAAA records\
   served by the parent zone cannot be queried explicitly.  Therefore,\
   after 100 seconds the AAAA record is removed from the cache(s), but\
   the A record remains.  Queries for the remaining 200 seconds\
   (provided that there are no further queries from the parent that\
   could refresh the caches) only return the A record, leading to a\
   potential operational situation with unreachable servers.\
\
   Similar cache flushing strategies apply in this scenario; the\
   behavior is likewise unspecified.\
\
4.5.  IPv6 Transport Guidelines for DNS Servers\
\
   As described in Section 1.3 and [RFC3901], there should continue to\
   be at least one authoritative IPv4 DNS server for every zone, even if\
   the zone has only IPv6 records.  (Note that obviously, having more\
   servers with robust connectivity would be preferable, but this is the\
   minimum recommendation; also see [RFC2182].)\
\
5.  Recommendations for DNS Resolver IPv6 Support\
\
   When IPv6 is enabled on a node, there are several things to consider\
   to ensure that the process is as smooth as possible.\
\
5.1.  DNS Lookups May Query IPv6 Records Prematurely\
\
   The system library that implements the getaddrinfo() function for\
   looking up names is a critical piece when considering the robustness\
   of enabling IPv6; it may come in basically three flavors:\
\
   1.  The system library does not know whether IPv6 has been enabled in\
       the kernel of the operating system: it may start looking up AAAA\
       records with getaddrinfo() and AF_UNSPEC hint when the system is\
       upgraded to a system library version that supports IPv6.\
\
   2.  The system library might start to perform IPv6 queries with\
       getaddrinfo() only when IPv6 has been enabled in the kernel.\
       However, this does not guarantee that there exists any useful\
       IPv6 connectivity (e.g., the node could be isolated from the\
       other IPv6 networks, only having link-local addresses).\
\
\
\
\
Durand, et al.               Informational                     [Page 10]\
\
RFC 4472              Considerations with IPv6 DNS            April 2006\
\
\
   3.  The system library might implement a toggle that would apply some\
       heuristics to the "IPv6-readiness" of the node before starting to\
       perform queries; for example, it could check whether only link-\
       local IPv6 address(es) exists, or if at least one global IPv6\
       address exists.\
\
   First, let us consider generic implications of unnecessary queries\
   for AAAA records: when looking up all the records in the DNS, AAAA\
   records are typically tried first, and then A records.  These are\
   done in serial, and the A query is not performed until a response is\
   received to the AAAA query.  Considering the misbehavior of DNS\
   servers and load-balancers, as described in Section 3.1, the lookup\
   delay for AAAA may incur additional unnecessary latency, and\
   introduce a component of unreliability.\
\
   One option here could be to do the queries partially in parallel; for\
   example, if the final response to the AAAA query is not received in\
   0.5 seconds, start performing the A query while waiting for the\
   result.  (Immediate parallelism might not be optimal, at least\
   without information-sharing between the lookup threads, as that would\
   probably lead to duplicate non-cached delegation chain lookups.)\
\
   An additional concern is the address selection, which may, in some\
   circumstances, prefer AAAA records over A records even when the node\
   does not have any IPv6 connectivity [WIP-RDP2004].  In some cases,\
   the implementation may attempt to connect or send a datagram on a\
   physical link [WIP-R2006], incurring very long protocol time-outs,\
   instead of quickly falling back to IPv4.\
\
   Now, we can consider the issues specific to each of the three\
   possibilities:\
\
   In the first case, the node performs a number of completely useless\
   DNS lookups as it will not be able to use the returned AAAA records\
   anyway.  (The only exception is where the application desires to know\
   what's in the DNS, but not use the result for communication.)  One\
   should be able to disable these unnecessary queries, for both latency\
   and reliability reasons.  However, as IPv6 has not been enabled, the\
   connections to IPv6 addresses fail immediately, and if the\
   application is programmed properly, the application can fall\
   gracefully back to IPv4 [RFC4038].\
\
   The second case is similar to the first, except it happens to a\
   smaller set of nodes when IPv6 has been enabled but connectivity has\
   not been provided yet.  Similar considerations apply, with the\
   exception that IPv6 records, when returned, will be actually tried\
   first, which may typically lead to long time-outs.\
\
\
\
\
Durand, et al.               Informational                     [Page 11]\
\
RFC 4472              Considerations with IPv6 DNS            April 2006\
\
\
   The third case is a bit more complex: optimizing away the DNS lookups\
   with only link-locals is probably safe (but may be desirable with\
   different lookup services that getaddrinfo() may support), as the\
   link-locals are typically automatically generated when IPv6 is\
   enabled, and do not indicate any form of IPv6 connectivity.  That is,\
   performing DNS lookups only when a non-link-local address has been\
   configured on any interface could be beneficial -- this would be an\
   indication that the address has been configured either from a router\
   advertisement, Dynamic Host Configuration Protocol for IPv6 (DHCPv6)\
   [RFC3315], or manually.  Each would indicate at least some form of\
   IPv6 connectivity, even though there would not be guarantees of it.\
\
   These issues should be analyzed at more depth, and the fixes found\
   consensus on, perhaps in a separate document.\
\
5.2.  Obtaining a List of DNS Recursive Resolvers\
\
   In scenarios where DHCPv6 is available, a host can discover a list of\
   DNS recursive resolvers through the DHCPv6 "DNS Recursive Name\
   Server" option [RFC3646].  This option can be passed to a host\
   through a subset of DHCPv6 [RFC3736].\
\
   The IETF is considering the development of alternative mechanisms for\
   obtaining the list of DNS recursive name servers when DHCPv6 is\
   unavailable or inappropriate.  No decision about taking on this\
   development work has been reached as of this writing [RFC4339].\
\
   In scenarios where DHCPv6 is unavailable or inappropriate, mechanisms\
   under consideration for development include the use of [WIP-O2004]\
   and the use of Router Advertisements to convey the information\
   [WIP-J2006].\
\
   Note that even though IPv6 DNS resolver discovery is a recommended\
   procedure, it is not required for dual-stack nodes in dual-stack\
   networks as IPv6 DNS records can be queried over IPv4 as well as\
   IPv6.  Obviously, nodes that are meant to function without manual\
   configuration in IPv6-only networks must implement the DNS resolver\
   discovery function.\
\
5.3.  IPv6 Transport Guidelines for Resolvers\
\
   As described in Section 1.3 and [RFC3901], the recursive resolvers\
   should be IPv4-only or dual-stack to be able to reach any IPv4-only\
   DNS server.  Note that this requirement is also fulfilled by an IPv6-\
   only stub resolver pointing to a dual-stack recursive DNS resolver.\
\
\
\
\
\
\
Durand, et al.               Informational                     [Page 12]\
\
RFC 4472              Considerations with IPv6 DNS            April 2006\
\
\
6.  Considerations about Forward DNS Updating\
\
   While the topic of how to enable updating the forward DNS, i.e., the\
   mapping from names to the correct new addresses, is not specific to\
   IPv6, it should be considered especially due to the advent of\
   Stateless Address Autoconfiguration [RFC2462].\
\
   Typically, forward DNS updates are more manageable than doing them in\
   the reverse DNS, because the updater can often be assumed to "own" a\
   certain DNS name -- and we can create a form of security relationship\
   with the DNS name and the node that is allowed to update it to point\
   to a new address.\
\
   A more complex form of DNS updates -- adding a whole new name into a\
   DNS zone, instead of updating an existing name -- is considered out\
   of scope for this memo as it could require zone-wide authentication.\
   Adding a new name in the forward zone is a problem that is still\
   being explored with IPv4, and IPv6 does not seem to add much new in\
   that area.\
\
6.1.  Manual or Custom DNS Updates\
\
   The DNS mappings can also be maintained by hand, in a semi-automatic\
   fashion or by running non-standardized protocols.  These are not\
   considered at more length in this memo.\
\
6.2.  Dynamic DNS\
\
   Dynamic DNS updates (DDNS) [RFC2136] [RFC3007] is a standardized\
   mechanism for dynamically updating the DNS.  It works equally well\
   with Stateless Address Autoconfiguration (SLAAC), DHCPv6, or manual\
   address configuration.  It is important to consider how each of these\
   behave if IP address-based authentication, instead of stronger\
   mechanisms [RFC3007], was used in the updates.\
\
   1.  Manual addresses are static and can be configured.\
\
   2.  DHCPv6 addresses could be reasonably static or dynamic, depending\
       on the deployment, and could or could not be configured on the\
       DNS server for the long term.\
\
   3.  SLAAC addresses are typically stable for a long time, but could\
       require work to be configured and maintained.\
\
   As relying on IP addresses for Dynamic DNS is rather insecure at\
   best, stronger authentication should always be used; however, this\
   requires that the authorization keying will be explicitly configured\
   using unspecified operational methods.\
\
\
\
Durand, et al.               Informational                     [Page 13]\
\
RFC 4472              Considerations with IPv6 DNS            April 2006\
\
\
   Note that with DHCP it is also possible that the DHCP server updates\
   the DNS, not the host.  The host might only indicate in the DHCP\
   exchange which hostname it would prefer, and the DHCP server would\
   make the appropriate updates.  Nonetheless, while this makes setting\
   up a secure channel between the updater and the DNS server easier, it\
   does not help much with "content" security, i.e., whether the\
   hostname was acceptable -- if the DNS server does not include\
   policies, they must be included in the DHCP server (e.g., a regular\
   host should not be able to state that its name is "www.example.com").\
   DHCP-initiated DDNS updates have been extensively described in\
   [WIP-SV2005], [WIP-S2005a], and [WIP-S2005b].\
\
   The nodes must somehow be configured with the information about the\
   servers where they will attempt to update their addresses, sufficient\
   security material for authenticating themselves to the server, and\
   the hostname they will be updating.  Unless otherwise configured, the\
   first could be obtained by looking up the authoritative name servers\
   for the hostname; the second must be configured explicitly unless one\
   chooses to trust the IP address-based authentication (not a good\
   idea); and lastly, the nodename is typically pre-configured somehow\
   on the node, e.g., at install time.\
\
   Care should be observed when updating the addresses not to use longer\
   TTLs for addresses than are preferred lifetimes for the addresses, so\
   that if the node is renumbered in a managed fashion, the amount of\
   stale DNS information is kept to the minimum.  That is, if the\
   preferred lifetime of an address expires, the TTL of the record needs\
   to be modified unless it was already done before the expiration.  For\
   better flexibility, the DNS TTL should be much shorter (e.g., a half\
   or a third) than the lifetime of an address; that way, the node can\
   start lowering the DNS TTL if it seems like the address has not been\
   renewed/refreshed in a while.  Some discussion on how an\
   administrator could manage the DNS TTL is included in [RFC4192]; this\
   could be applied to (smart) hosts as well.\
\
7.  Considerations about Reverse DNS Updating\
\
   Updating the reverse DNS zone may be difficult because of the split\
   authority over an address.  However, first we have to consider the\
   applicability of reverse DNS in the first place.\
\
7.1.  Applicability of Reverse DNS\
\
   Today, some applications use reverse DNS either to look up some hints\
   about the topological information associated with an address (e.g.,\
   resolving web server access logs) or (as a weak form of a security\
   check) to get a feel whether the user's network administrator has\
\
\
\
\
Durand, et al.               Informational                     [Page 14]\
\
RFC 4472              Considerations with IPv6 DNS            April 2006\
\
\
   "authorized" the use of the address (on the premise that adding a\
   reverse record for an address would signal some form of\
   authorization).\
\
   One additional, maybe slightly more useful usage is ensuring that the\
   reverse and forward DNS contents match (by looking up the pointer to\
   the name by the IP address from the reverse tree, and ensuring that a\
   record under the name in the forward tree points to the IP address)\
   and correspond to a configured name or domain.  As a security check,\
   it is typically accompanied by other mechanisms, such as a user/\
   password login; the main purpose of the reverse+forward DNS check is\
   to weed out the majority of unauthorized users, and if someone\
   managed to bypass the checks, he would still need to authenticate\
   "properly".\
\
   It may also be desirable to store IPsec keying material corresponding\
   to an IP address in the reverse DNS, as justified and described in\
   [RFC4025].\
\
   It is not clear whether it makes sense to require or recommend that\
   reverse DNS records be updated.  In many cases, it would just make\
   more sense to use proper mechanisms for security (or topological\
   information lookup) in the first place.  At minimum, the applications\
   that use it as a generic authorization (in the sense that a record\
   exists at all) should be modified as soon as possible to avoid such\
   lookups completely.\
\
   The applicability is discussed at more length in [WIP-S2005c].\
\
7.2.  Manual or Custom DNS Updates\
\
   Reverse DNS can of course be updated using manual or custom methods.\
   These are not further described here, except for one special case.\
\
   One way to deploy reverse DNS would be to use wildcard records, for\
   example, by configuring one name for a subnet (/64) or a site (/48).\
   As a concrete example, a site (or the site's ISP) could configure the\
   reverses of the prefix 2001:db8:f00::/48 to point to one name using a\
   wildcard record like "*.0.0.f.0.8.b.d.0.1.0.0.2.ip6.arpa. IN PTR\
   site.example.com.".  Naturally, such a name could not be verified\
   from the forward DNS, but would at least provide some form of\
   "topological information" or "weak authorization" if that is really\
   considered to be useful.  Note that this is not actually updating the\
   DNS as such, as the whole point is to avoid DNS updates completely by\
   manually configuring a generic name.\
\
\
\
\
\
\
Durand, et al.               Informational                     [Page 15]\
\
RFC 4472              Considerations with IPv6 DNS            April 2006\
\
\
7.3.  DDNS with Stateless Address Autoconfiguration\
\
   Dynamic reverse DNS with SLAAC is simpler than forward DNS updates in\
   some regard, while being more difficult in another, as described\
   below.\
\
   The address space administrator decides whether or not the hosts are\
   trusted to update their reverse DNS records.  If they are trusted and\
   deployed at the same site (e.g., not across the Internet), a simple\
   address-based authorization is typically sufficient (i.e., check that\
   the DNS update is done from the same IP address as the record being\
   updated); stronger security can also be used [RFC3007].  If they\
   aren't allowed to update the reverses, no update can occur.  However,\
   such address-based update authorization operationally requires that\
   ingress filtering [RFC3704] has been set up at the border of the site\
   where the updates occur, and as close to the updater as possible.\
\
   Address-based authorization is simpler with reverse DNS (as there is\
   a connection between the record and the address) than with forward\
   DNS.  However, when a stronger form of security is used, forward DNS\
   updates are simpler to manage because the host can be assumed to have\
   an association with the domain.  Note that the user may roam to\
   different networks and does not necessarily have any association with\
   the owner of that address space.  So, assuming a stronger form of\
   authorization for reverse DNS updates than an address association is\
   generally infeasible.\
\
   Moreover, the reverse zones must be cleaned up by an unspecified\
   janitorial process: the node does not typically know a priori that it\
   will be disconnected, and it cannot send a DNS update using the\
   correct source address to remove a record.\
\
   A problem with defining the clean-up process is that it is difficult\
   to ensure that a specific IP address and the corresponding record are\
   no longer being used.  Considering the huge address space, and the\
   unlikelihood of collision within 64 bits of the interface\
   identifiers, a process that would remove the record after no traffic\
   has been seen from a node in a long period of time (e.g., a month or\
   year) might be one possible approach.\
\
   To insert or update the record, the node must discover the DNS server\
   to send the update to somehow, similar to as discussed in\
   Section 6.2.  One way to automate this is looking up the DNS server\
   authoritative (e.g., through SOA record) for the IP address being\
   updated, but the security material (unless the IP address-based\
   authorization is trusted) must also be established by some other\
   means.\
\
\
\
\
Durand, et al.               Informational                     [Page 16]\
\
RFC 4472              Considerations with IPv6 DNS            April 2006\
\
\
   One should note that Cryptographically Generated Addresses (CGAs)\
   [RFC3972] may require a slightly different kind of treatment.  CGAs\
   are addresses where the interface identifier is calculated from a\
   public key, a modifier (used as a nonce), the subnet prefix, and\
   other data.  Depending on the usage profile, CGAs might or might not\
   be changed periodically due to, e.g., privacy reasons.  As the CGA\
   address is not predictable, a reverse record can only reasonably be\
   inserted in the DNS by the node that generates the address.\
\
7.4.  DDNS with DHCP\
\
   With DHCPv4, the reverse DNS name is typically already inserted to\
   the DNS that reflects the name (e.g., "dhcp-67.example.com").  One\
   can assume similar practice may become commonplace with DHCPv6 as\
   well; all such mappings would be pre-configured and would require no\
   updating.\
\
   If a more explicit control is required, similar considerations as\
   with SLAAC apply, except for the fact that typically one must update\
   a reverse DNS record instead of inserting one (if an address\
   assignment policy that reassigns disused addresses is adopted) and\
   updating a record seems like a slightly more difficult thing to\
   secure.  However, it is yet uncertain how DHCPv6 is going to be used\
   for address assignment.\
\
   Note that when using DHCP, either the host or the DHCP server could\
   perform the DNS updates; see the implications in Section 6.2.\
\
   If disused addresses were to be reassigned, host-based DDNS reverse\
   updates would need policy considerations for DNS record modification,\
   as noted above.  On the other hand, if disused address were not to be\
   assigned, host-based DNS reverse updates would have similar\
   considerations as SLAAC in Section 7.3.  Server-based updates have\
   similar properties except that the janitorial process could be\
   integrated with DHCP address assignment.\
\
7.5.  DDNS with Dynamic Prefix Delegation\
\
   In cases where a prefix, instead of an address, is being used and\
   updated, one should consider what is the location of the server where\
   DDNS updates are made.  That is, where the DNS server is located:\
\
   1.  At the same organization as the prefix delegator.\
\
   2.  At the site where the prefixes are delegated to.  In this case,\
       the authority of the DNS reverse zone corresponding to the\
       delegated prefix is also delegated to the site.\
\
\
\
\
Durand, et al.               Informational                     [Page 17]\
\
RFC 4472              Considerations with IPv6 DNS            April 2006\
\
\
   3.  Elsewhere; this implies a relationship between the site and where\
       the DNS server is located, and such a relationship should be\
       rather straightforward to secure as well.  Like in the previous\
       case, the authority of the DNS reverse zone is also delegated.\
\
   In the first case, managing the reverse DNS (delegation) is simpler\
   as the DNS server and the prefix delegator are in the same\
   administrative domain (as there is no need to delegate anything at\
   all); alternatively, the prefix delegator might forgo DDNS reverse\
   capability altogether, and use, e.g., wildcard records (as described\
   in Section 7.2).  In the other cases, it can be slightly more\
   difficult, particularly as the site will have to configure the DNS\
   server to be authoritative for the delegated reverse zone, implying\
   automatic configuration of the DNS server -- as the prefix may be\
   dynamic.\
\
   Managing the DDNS reverse updates is typically simple in the second\
   case, as the updated server is located at the local site, and\
   arguably IP address-based authentication could be sufficient (or if\
   not, setting up security relationships would be simpler).  As there\
   is an explicit (security) relationship between the parties in the\
   third case, setting up the security relationships to allow reverse\
   DDNS updates should be rather straightforward as well (but IP\
   address-based authentication might not be acceptable).  In the first\
   case, however, setting up and managing such relationships might be a\
   lot more difficult.\
\
8.  Miscellaneous DNS Considerations\
\
   This section describes miscellaneous considerations about DNS that\
   seem related to IPv6, for which no better place has been found in\
   this document.\
\
8.1.  NAT-PT with DNS-ALG\
\
   The DNS-ALG component of NAT-PT [RFC2766] mangles A records to look\
   like AAAA records to the IPv6-only nodes.  Numerous problems have\
   been identified with [WIP-AD2005].  This is a strong reason not to\
   use NAT-PT in the first place.\
\
8.2.  Renumbering Procedures and Applications' Use of DNS\
\
   One of the most difficult problems of systematic IP address\
   renumbering procedures [RFC4192] is that an application that looks up\
   a DNS name disregards information such as TTL, and uses the result\
   obtained from DNS as long as it happens to be stored in the memory of\
   the application.  For applications that run for a long time, this\
\
\
\
\
Durand, et al.               Informational                     [Page 18]\
\
RFC 4472              Considerations with IPv6 DNS            April 2006\
\
\
   could be days, weeks, or even months.  Some applications may be\
   clever enough to organize the data structures and functions in such a\
   manner that lookups get refreshed now and then.\
\
   While the issue appears to have a clear solution, "fix the\
   applications", practically, this is not reasonable immediate advice.\
   The TTL information is not typically available in the APIs and\
   libraries (so, the advice becomes "fix the applications, APIs, and\
   libraries"), and a lot more analysis is needed on how to practically\
   go about to achieve the ultimate goal of avoiding using the names\
   longer than expected.\
\
9.  Acknowledgements\
\
   Some recommendations (Section 4.3, Section 5.1) about IPv6 service\
   provisioning were moved here from [RFC4213] by Erik Nordmark and Bob\
   Gilligan.  Havard Eidnes and Michael Patton provided useful feedback\
   and improvements.  Scott Rose, Rob Austein, Masataka Ohta, and Mark\
   Andrews helped in clarifying the issues regarding additional data and\
   the use of TTL.  Jefsey Morfin, Ralph Droms, Peter Koch, Jinmei\
   Tatuya, Iljitsch van Beijnum, Edward Lewis, and Rob Austein provided\
   useful feedback during the WG last call.  Thomas Narten provided\
   extensive feedback during the IESG evaluation.\
\
10.  Security Considerations\
\
   This document reviews the operational procedures for IPv6 DNS\
   operations and does not have security considerations in itself.\
\
   However, it is worth noting that in particular with Dynamic DNS\
   updates, security models based on the source address validation are\
   very weak and cannot be recommended -- they could only be considered\
   in the environments where ingress filtering [RFC3704] has been\
   deployed.  On the other hand, it should be noted that setting up an\
   authorization mechanism (e.g., a shared secret, or public-private\
   keys) between a node and the DNS server has to be done manually, and\
   may require quite a bit of time and expertise.\
\
   To re-emphasize what was already stated, the reverse+forward DNS\
   check provides very weak security at best, and the only\
   (questionable) security-related use for them may be in conjunction\
   with other mechanisms when authenticating a user.\
\
\
\
\
\
\
\
\
\
Durand, et al.               Informational                     [Page 19]\
\
RFC 4472              Considerations with IPv6 DNS            April 2006\
\
\
11.  References\
\
11.1.  Normative References\
\
   [RFC1034]     Mockapetris, P., "Domain names - concepts and\
                 facilities", STD 13, RFC 1034, November 1987.\
\
   [RFC2136]     Vixie, P., Thomson, S., Rekhter, Y., and J. Bound,\
                 "Dynamic Updates in the Domain Name System (DNS\
                 UPDATE)", RFC 2136, April 1997.\
\
   [RFC2181]     Elz, R. and R. Bush, "Clarifications to the DNS\
                 Specification", RFC 2181, July 1997.\
\
   [RFC2182]     Elz, R., Bush, R., Bradner, S., and M. Patton,\
                 "Selection and Operation of Secondary DNS Servers",\
                 BCP 16, RFC 2182, July 1997.\
\
   [RFC2462]     Thomson, S. and T. Narten, "IPv6 Stateless Address\
                 Autoconfiguration", RFC 2462, December 1998.\
\
   [RFC2671]     Vixie, P., "Extension Mechanisms for DNS (EDNS0)",\
                 RFC 2671, August 1999.\
\
   [RFC2821]     Klensin, J., "Simple Mail Transfer Protocol", RFC 2821,\
                 April 2001.\
\
   [RFC3007]     Wellington, B., "Secure Domain Name System (DNS)\
                 Dynamic Update", RFC 3007, November 2000.\
\
   [RFC3041]     Narten, T. and R. Draves, "Privacy Extensions for\
                 Stateless Address Autoconfiguration in IPv6", RFC 3041,\
                 January 2001.\
\
   [RFC3056]     Carpenter, B. and K. Moore, "Connection of IPv6 Domains\
                 via IPv4 Clouds", RFC 3056, February 2001.\
\
   [RFC3152]     Bush, R., "Delegation of IP6.ARPA", BCP 49, RFC 3152,\
                 August 2001.\
\
   [RFC3315]     Droms, R., Bound, J., Volz, B., Lemon, T., Perkins, C.,\
                 and M. Carney, "Dynamic Host Configuration Protocol for\
                 IPv6 (DHCPv6)", RFC 3315, July 2003.\
\
   [RFC3363]     Bush, R., Durand, A., Fink, B., Gudmundsson, O., and T.\
                 Hain, "Representing Internet Protocol version 6 (IPv6)\
                 Addresses in the Domain Name System (DNS)", RFC 3363,\
                 August 2002.\
\
\
\
Durand, et al.               Informational                     [Page 20]\
\
RFC 4472              Considerations with IPv6 DNS            April 2006\
\
\
   [RFC3364]     Austein, R., "Tradeoffs in Domain Name System (DNS)\
                 Support for Internet Protocol version 6 (IPv6)",\
                 RFC 3364, August 2002.\
\
   [RFC3596]     Thomson, S., Huitema, C., Ksinant, V., and M. Souissi,\
                 "DNS Extensions to Support IP Version 6", RFC 3596,\
                 October 2003.\
\
   [RFC3646]     Droms, R., "DNS Configuration options for Dynamic Host\
                 Configuration Protocol for IPv6 (DHCPv6)", RFC 3646,\
                 December 2003.\
\
   [RFC3736]     Droms, R., "Stateless Dynamic Host Configuration\
                 Protocol (DHCP) Service for IPv6", RFC 3736,\
                 April 2004.\
\
   [RFC3879]     Huitema, C. and B. Carpenter, "Deprecating Site Local\
                 Addresses", RFC 3879, September 2004.\
\
   [RFC3901]     Durand, A. and J. Ihren, "DNS IPv6 Transport\
                 Operational Guidelines", BCP 91, RFC 3901,\
                 September 2004.\
\
   [RFC4038]     Shin, M-K., Hong, Y-G., Hagino, J., Savola, P., and E.\
                 Castro, "Application Aspects of IPv6 Transition",\
                 RFC 4038, March 2005.\
\
   [RFC4074]     Morishita, Y. and T. Jinmei, "Common Misbehavior\
                 Against DNS Queries for IPv6 Addresses", RFC 4074,\
                 May 2005.\
\
   [RFC4192]     Baker, F., Lear, E., and R. Droms, "Procedures for\
                 Renumbering an IPv6 Network without a Flag Day",\
                 RFC 4192, September 2005.\
\
   [RFC4193]     Hinden, R. and B. Haberman, "Unique Local IPv6 Unicast\
                 Addresses", RFC 4193, October 2005.\
\
   [RFC4291]     Hinden, R. and S. Deering, "IP Version 6 Addressing\
                 Architecture", RFC 4291, February 2006.\
\
   [RFC4339]     Jeong, J., Ed., "IPv6 Host Configuration of DNS Server\
                 Information Approaches", RFC 4339, February 2006.\
\
\
\
\
\
\
\
\
Durand, et al.               Informational                     [Page 21]\
\
RFC 4472              Considerations with IPv6 DNS            April 2006\
\
\
11.2.  Informative References\
\
   [RFC2766]     Tsirtsis, G. and P. Srisuresh, "Network Address\
                 Translation - Protocol Translation (NAT-PT)", RFC 2766,\
                 February 2000.\
\
   [RFC2782]     Gulbrandsen, A., Vixie, P., and L. Esibov, "A DNS RR\
                 for specifying the location of services (DNS SRV)",\
                 RFC 2782, February 2000.\
\
   [RFC2826]     Internet Architecture Board, "IAB Technical Comment on\
                 the Unique DNS Root", RFC 2826, May 2000.\
\
   [RFC3704]     Baker, F. and P. Savola, "Ingress Filtering for\
                 Multihomed Networks", BCP 84, RFC 3704, March 2004.\
\
   [RFC3972]     Aura, T., "Cryptographically Generated Addresses\
                 (CGA)", RFC 3972, March 2005.\
\
   [RFC4025]     Richardson, M., "A Method for Storing IPsec Keying\
                 Material in DNS", RFC 4025, March 2005.\
\
   [RFC4213]     Nordmark, E. and R. Gilligan, "Basic Transition\
                 Mechanisms for IPv6 Hosts and Routers", RFC 4213,\
                 October 2005.\
\
   [RFC4215]     Wiljakka, J., "Analysis on IPv6 Transition in Third\
                 Generation Partnership Project (3GPP) Networks",\
                 RFC 4215, October 2005.\
\
   [RFC4380]     Huitema, C., "Teredo: Tunneling IPv6 over UDP through\
                 Network Address Translations (NATs)", RFC 4380,\
                 February 2006.\
\
   [TC-TEST]     Jinmei, T., "Thread "RFC2181 section 9.1: TC bit\
                 handling and additional data" on DNSEXT mailing list,\
                 Message-\
                 Id:y7vek9j9hyo.wl%jinmei@isl.rdc.toshiba.co.jp", August\
                 1, 2005, <http://ops.ietf.org/lists/namedroppers/\
                 namedroppers.2005/msg01102.html>.\
\
   [WIP-AD2005]  Aoun, C. and E. Davies, "Reasons to Move NAT-PT to\
                 Experimental", Work in Progress, October 2005.\
\
   [WIP-DC2005]  Durand, A. and T. Chown, "To publish, or not to\
                 publish, that is the question", Work in Progress,\
                 October 2005.\
\
\
\
\
Durand, et al.               Informational                     [Page 22]\
\
RFC 4472              Considerations with IPv6 DNS            April 2006\
\
\
   [WIP-H2005]   Huston, G., "6to4 Reverse DNS Delegation\
                 Specification", Work in Progress, November 2005.\
\
   [WIP-J2006]   Jeong, J., "IPv6 Router Advertisement Option for DNS\
                 Configuration", Work in Progress, January 2006.\
\
   [WIP-LB2005]  Larson, M. and P. Barber, "Observed DNS Resolution\
                 Misbehavior", Work in Progress, February 2006.\
\
   [WIP-O2004]   Ohta, M., "Preconfigured DNS Server Addresses", Work in\
                 Progress, February 2004.\
\
   [WIP-R2006]   Roy, S., "IPv6 Neighbor Discovery On-Link Assumption\
                 Considered Harmful", Work in Progress, January 2006.\
\
   [WIP-RDP2004] Roy, S., Durand, A., and J. Paugh, "Issues with Dual\
                 Stack IPv6 on by Default", Work in Progress, July 2004.\
\
   [WIP-S2005a]  Stapp, M., "The DHCP Client FQDN Option", Work in\
                 Progress, March 2006.\
\
   [WIP-S2005b]  Stapp, M., "A DNS RR for Encoding DHCP Information\
                 (DHCID RR)", Work in Progress, March 2006.\
\
   [WIP-S2005c]  Senie, D., "Encouraging the use of DNS IN-ADDR\
                 Mapping", Work in Progress, August 2005.\
\
   [WIP-SV2005]  Stapp, M. and B. Volz, "Resolution of FQDN Conflicts\
                 among DHCP Clients", Work in Progress, March 2006.\
\
\
\
\
\
\
\
\
\
\
\
\
\
\
\
\
\
\
\
\
\
\
Durand, et al.               Informational                     [Page 23]\
\
RFC 4472              Considerations with IPv6 DNS            April 2006\
\
\
Appendix A.  Unique Local Addressing Considerations for DNS\
\
   Unique local addresses [RFC4193] have replaced the now-deprecated\
   site-local addresses [RFC3879].  From the perspective of the DNS, the\
   locally generated unique local addresses (LUL) and site-local\
   addresses have similar properties.\
\
   The interactions with DNS come in two flavors: forward and reverse\
   DNS.\
\
   To actually use local addresses within a site, this implies the\
   deployment of a "split-faced" or a fragmented DNS name space, for the\
   zones internal to the site, and the outsiders' view to it.  The\
   procedures to achieve this are not elaborated here.  The implication\
   is that local addresses must not be published in the public DNS.\
\
   To facilitate reverse DNS (if desired) with local addresses, the stub\
   resolvers must look for DNS information from the local DNS servers,\
   not, e.g., starting from the root servers, so that the local\
   information may be provided locally.  Note that the experience of\
   private addresses in IPv4 has shown that the root servers get loaded\
   for requests for private address lookups in any case.  This\
   requirement is discussed in [RFC4193].\
\
Appendix B.  Behavior of Additional Data in IPv4/IPv6 Environments\
\
   DNS responses do not always fit in a single UDP packet.  We'll\
   examine the cases that happen when this is due to too much data in\
   the Additional section.\
\
B.1.  Description of Additional Data Scenarios\
\
   There are two kinds of additional data:\
\
   1.  "critical" additional data; this must be included in all\
       scenarios, with all the RRsets, and\
\
   2.  "courtesy" additional data; this could be sent in full, with only\
       a few RRsets, or with no RRsets, and can be fetched separately as\
       well, but at the cost of additional queries.\
\
   The responding server can algorithmically determine which type the\
   additional data is by checking whether it's at or below a zone cut.\
\
   Only those additional data records (even if sometimes carelessly\
   termed "glue") are considered "critical" or real "glue" if and only\
   if they meet the above-mentioned condition, as specified in Section\
   4.2.1 of [RFC1034].\
\
\
\
Durand, et al.               Informational                     [Page 24]\
\
RFC 4472              Considerations with IPv6 DNS            April 2006\
\
\
   Remember that resource record sets (RRsets) are never "broken up", so\
   if a name has 4 A records and 5 AAAA records, you can either return\
   all 9, all 4 A records, all 5 AAAA records, or nothing.  In\
   particular, notice that for the "critical" additional data getting\
   all the RRsets can be critical.\
\
   In particular, [RFC2181] specifies (in Section 9) that:\
\
   a.  if all the "critical" RRsets do not fit, the sender should set\
       the TC bit, and the recipient should discard the whole response\
       and retry using mechanism allowing larger responses such as TCP.\
\
   b.  "courtesy" additional data should not cause the setting of the TC\
       bit, but instead all the non-fitting additional data RRsets\
       should be removed.\
\
   An example of the "courtesy" additional data is A/AAAA records in\
   conjunction with MX records as shown in Section 4.4; an example of\
   the "critical" additional data is shown below (where getting both the\
   A and AAAA RRsets is critical with respect to the NS RR):\
\
      child.example.com.    IN   NS ns.child.example.com.\
      ns.child.example.com. IN    A 192.0.2.1\
      ns.child.example.com. IN AAAA 2001:db8::1\
\
   When there is too much "courtesy" additional data, at least the non-\
   fitting RRsets should be removed [RFC2181]; however, as the\
   additional data is not critical, even all of it could be safely\
   removed.\
\
   When there is too much "critical" additional data, TC bit will have\
   to be set, and the recipient should ignore the response and retry\
   using TCP; if some data were to be left in the UDP response, the\
   issue is which data could be retained.\
\
   However, the practice may differ from the specification.  Testing and\
   code analysis of three recent implementations [TC-TEST] confirm this.\
   None of the tested implementations have a strict separation of\
   critical and courtesy additional data, while some forms of additional\
   data may be treated preferably.  All the implementations remove some\
   (critical or courtesy) additional data RRsets without setting the TC\
   bit if the response would not otherwise fit.\
\
   Failing to discard the response with the TC bit or omitting critical\
   information but not setting the TC bit lead to an unrecoverable\
   problem.  Omitting only some of the RRsets if all would not fit (but\
   not setting the TC bit) leads to a performance problem.  These are\
   discussed in the next two subsections.\
\
\
\
Durand, et al.               Informational                     [Page 25]\
\
RFC 4472              Considerations with IPv6 DNS            April 2006\
\
\
B.2.  Which Additional Data to Keep, If Any?\
\
   NOTE: omitting some critical additional data instead of setting the\
   TC bit violates a 'should' in Section 9 of RFC2181.  However, as many\
   implementations still do that [TC-TEST], operators need to understand\
   its implications, and we describe that behavior as well.\
\
   If the implementation decides to keep as much data (whether\
   "critical" or "courtesy") as possible in the UDP responses, it might\
   be tempting to use the transport of the DNS query as a hint in either\
   of these cases: return the AAAA records if the query was done over\
   IPv6, or return the A records if the query was done over IPv4.\
   However, this breaks the model of independence of DNS transport and\
   resource records, as noted in Section 1.2.\
\
   With courtesy additional data, as long as enough RRsets will be\
   removed so that TC will not be set, it is allowed to send as many\
   complete RRsets as the implementations prefers.  However, the\
   implementations are also free to omit all such RRsets, even if\
   complete.  Omitting all the RRsets (when removing only some would\
   suffice) may create a performance penalty, whereby the client may\
   need to issue one or more additional queries to obtain necessary\
   and/or consistent information.\
\
   With critical additional data, the alternatives are either returning\
   nothing (and absolutely requiring a retry with TCP) or returning\
   something (working also in the case if the recipient does not discard\
   the response and retry using TCP) in addition to setting the TC bit.\
   If the process for selecting "something" from the critical data would\
   otherwise be practically "flipping the coin" between A and AAAA\
   records, it could be argued that if one looked at the transport of\
   the query, it would have a larger possibility of being right than\
   just 50/50.  In other words, if the returned critical additional data\
   would have to be selected somehow, using something more sophisticated\
   than a random process would seem justifiable.\
\
   That is, leaving in some intelligently selected critical additional\
   data is a trade-off between creating an optimization for those\
   resolvers that ignore the "should discard" recommendation and causing\
   a protocol problem by propagating inconsistent information about\
   "critical" records in the caches.\
\
   Similarly, leaving in the complete courtesy additional data RRsets\
   instead of removing all the RRsets is a performance trade-off as\
   described in the next section.\
\
\
\
\
\
\
Durand, et al.               Informational                     [Page 26]\
\
RFC 4472              Considerations with IPv6 DNS            April 2006\
\
\
B.3.  Discussion of the Potential Problems\
\
   As noted above, the temptation for omitting only some of the\
   additional data could be problematic.  This is discussed more below.\
\
   For courtesy additional data, this causes a potential performance\
   problem as this requires that the clients issue re-queries for the\
   potentially omitted RRsets.  For critical additional data, this\
   causes a potential unrecoverable problem if the response is not\
   discarded and the query not re-tried with TCP, as the nameservers\
   might be reachable only through the omitted RRsets.\
\
   If an implementation would look at the transport used for the query,\
   it is worth remembering that often the host using the records is\
   different from the node requesting them from the authoritative DNS\
   server (or even a caching resolver).  So, whichever version the\
   requestor (e.g., a recursive server in the middle) uses makes no\
   difference to the ultimate user of the records, whose transport\
   capabilities might differ from those of the requestor.  This might\
   result in, e.g., inappropriately returning A records to an IPv6-only\
   node, going through a translation, or opening up another IP-level\
   session (e.g., a Packet Data Protocol (PDP) context [RFC4215]).\
   Therefore, at least in many scenarios, it would be very useful if the\
   information returned would be consistent and complete -- or if that\
   is not feasible, leave it to the client to query again.\
\
   The problem of too much additional data seems to be an operational\
   one: the zone administrator entering too many records that will be\
   returned truncated (or missing some RRsets, depending on\
   implementations) to the users.  A protocol fix for this is using\
   Extension Mechanisms for DNS (EDNS0) [RFC2671] to signal the capacity\
   for larger UDP packet sizes, pushing up the relevant threshold.\
   Further, DNS server implementations should omit courtesy additional\
   data completely rather than including only some RRsets [RFC2181].  An\
   operational fix for this is having the DNS server implementations\
   return a warning when the administrators create zones that would\
   result in too much additional data being returned.  Further, DNS\
   server implementations should warn of or disallow such zone\
   configurations that are recursive or otherwise difficult to manage by\
   the protocol.\
\
\
\
\
\
\
\
\
\
\
\
Durand, et al.               Informational                     [Page 27]\
\
RFC 4472              Considerations with IPv6 DNS            April 2006\
\
\
Authors' Addresses\
\
   Alain Durand\
   Comcast\
   1500 Market St.\
   Philadelphia, PA  19102\
   USA\
\
   EMail: Alain_Durand@cable.comcast.com\
\
\
   Johan Ihren\
   Autonomica\
   Bellmansgatan 30\
   SE-118 47 Stockholm\
   Sweden\
\
   EMail: johani@autonomica.se\
\
\
   Pekka Savola\
   CSC/FUNET\
   Espoo\
   Finland\
\
   EMail: psavola@funet.fi\
\
\
\
\
\
\
\
\
\
\
\
\
\
\
\
\
\
\
\
\
\
\
\
\
\
Durand, et al.               Informational                     [Page 28]\
\
RFC 4472              Considerations with IPv6 DNS            April 2006\
\
\
Full Copyright Statement\
\
   Copyright (C) The Internet Society (2006).\
\
   This document is subject to the rights, licenses and restrictions\
   contained in BCP 78, and except as set forth therein, the authors\
   retain all their rights.\
\
   This document and the information contained herein are provided on an\
   "AS IS" basis and THE CONTRIBUTOR, THE ORGANIZATION HE/SHE REPRESENTS\
   OR IS SPONSORED BY (IF ANY), THE INTERNET SOCIETY AND THE INTERNET\
   ENGINEERING TASK FORCE DISCLAIM ALL WARRANTIES, EXPRESS OR IMPLIED,\
   INCLUDING BUT NOT LIMITED TO ANY WARRANTY THAT THE USE OF THE\
   INFORMATION HEREIN WILL NOT INFRINGE ANY RIGHTS OR ANY IMPLIED\
   WARRANTIES OF MERCHANTABILITY OR FITNESS FOR A PARTICULAR PURPOSE.\
\
Intellectual Property\
\
   The IETF takes no position regarding the validity or scope of any\
   Intellectual Property Rights or other rights that might be claimed to\
   pertain to the implementation or use of the technology described in\
   this document or the extent to which any license under such rights\
   might or might not be available; nor does it represent that it has\
   made any independent effort to identify any such rights.  Information\
   on the procedures with respect to rights in RFC documents can be\
   found in BCP 78 and BCP 79.\
\
   Copies of IPR disclosures made to the IETF Secretariat and any\
   assurances of licenses to be made available, or the result of an\
   attempt made to obtain a general license or permission for the use of\
   such proprietary rights by implementers or users of this\
   specification can be obtained from the IETF on-line IPR repository at\
   http://www.ietf.org/ipr.\
\
   The IETF invites any interested party to bring to its attention any\
   copyrights, patents or patent applications, or other proprietary\
   rights that may cover technology that may be required to implement\
   this standard.  Please address the information to the IETF at\
   ietf-ipr@ietf.org.\
\
Acknowledgement\
\
   Funding for the RFC Editor function is provided by the IETF\
   Administrative Support Activity (IASA).\
\
\
\
\
\
\
\
Durand, et al.               Informational                     [Page 29]\
\

doc 13
  field 0
    name titolo
    type string
    value rfc4473.txt
  field 1
    name contenuto
    type string
    value \
\
\
\
\
\
Network Working Group                                          Y. Nomura\
Request for Comments: 4473                                  Fujitsu Labs\
Category: Informational                                         R. Walsh\
                                                              J-P. Luoma\
                                                                   Nokia\
                                                                  J. Ott\
                                       Helsinki University of Technology\
                                                          H. Schulzrinne\
                                                     Columbia University\
                                                                May 2006\
\
\
             Requirements for Internet Media Guides (IMGs)\
\
Status of This Memo\
\
   This memo provides information for the Internet community.  It does\
   not specify an Internet standard of any kind.  Distribution of this\
   memo is unlimited.\
\
Copyright Notice\
\
   Copyright (C) The Internet Society (2006).\
\
Abstract\
\
   This memo specifies requirements for a framework and protocols for\
   accessing and updating Internet Media Guide (IMG) information for\
   media-on-demand and multicast applications.  These requirements are\
   designed to guide choice and development of IMG protocols for\
   efficient and scalable delivery.\
\
\
\
\
\
\
\
\
\
\
\
\
\
\
\
\
\
\
\
\
Nomura, et al.               Informational                      [Page 1]\
\
RFC 4473     Requirements for Internet Media Guides (IMGs)      May 2006\
\
\
Table of Contents\
\
   1. Introduction ....................................................3\
      1.1. Background and Motivation ..................................3\
      1.2. Scope of This Document .....................................4\
   2. Terminology .....................................................5\
      2.1. New Terms ..................................................5\
   3. Problem Statement ...............................................6\
   4. Use Cases Requiring IMGs ........................................7\
      4.1. Connectivity-based Use Cases ...............................7\
           4.1.1. IP Datacast to a Wireless Receiver ..................7\
           4.1.2. Regular Fixed Dial-up Internet Connection ...........8\
           4.1.3. Broadband Always-on Fixed Internet Connection .......9\
      4.2. Content-orientated Use Cases ...............................9\
           4.2.1. TV and Radio Program Delivery .......................9\
           4.2.2. Media Coverage of a Live Event .....................10\
           4.2.3. Distance Learning ..................................10\
           4.2.4. Multiplayer Gaming .................................10\
           4.2.5. File Distribution ..................................11\
           4.2.6. Coming-release and Pre-released Content ............11\
   5. Requirements ...................................................11\
      5.1. General Requirements ......................................11\
           5.1.1. Independence of IMG Operations from IMG Metadata ...11\
           5.1.2. Multiple IMG Senders ...............................12\
           5.1.3. Modularity .........................................12\
      5.2. Delivery Properties .......................................12\
           5.2.1. Scalability ........................................13\
           5.2.2. Support for Intermittent Connectivity ..............13\
           5.2.3. Congestion Control .................................13\
           5.2.4. Sender- and Receiver-Driven Delivery ...............13\
      5.3. Customized IMGs ...........................................14\
      5.4. Reliability ...............................................15\
           5.4.1. Managing Consistency ...............................15\
           5.4.2. Reliable Message Exchange ..........................16\
      5.5. IMG Descriptions ..........................................16\
   6. Security Considerations ........................................17\
      6.1. IMG Authentication and Integrity ..........................18\
      6.2. Privacy ...................................................19\
      6.3. Access Control for IMGs ...................................19\
      6.4. Denial-of-Service (DOS) Attacks ...........................20\
      6.5. Replay Attacks ............................................20\
   7. Normative References ...........................................21\
   8. Informative References .........................................21\
   9. Acknowledgements ...............................................22\
\
\
\
\
\
\
\
Nomura, et al.               Informational                      [Page 2]\
\
RFC 4473     Requirements for Internet Media Guides (IMGs)      May 2006\
\
\
1.  Introduction\
\
1.1.  Background and Motivation\
\
   For some ten years, multicast-based (multimedia) conferences\
   (including IETF working group sessions) as well as broadcasts of\
   lectures/seminars, concerts, and other events have been used in the\
   Internet, more precisely, on the MBONE.  Schedules and descriptions\
   for such multimedia sessions as well as the transport addresses,\
   codecs, and their parameters have been described using the Session\
   Description Protocol (SDP) [2] as a rudimentary (but as of then\
   largely sufficient) means.  Descriptions have been disseminated using\
   the Session Announcement Protocol (SAP) [3] and Session Directory\
   Tools such as SD [4] or SDR [5]; descriptions have also been put up\
   on web pages, sent by electronic mail, etc.\
\
   Recently, interest has grown to expand -- or better: to generalize --\
   the applicability of these kinds of session descriptions.\
   Descriptions are becoming more elaborate in terms of included\
   metadata, more generic regarding the types of media sessions, and\
   possibly also support other transports than just IP (e.g., legacy TV\
   channel addresses).  This peers well with the DVB (Digital Video\
   Broadcasting) [6] Organization's increased activities towards IP-\
   based communications over satellite, cable, and terrestrial radio\
   networks, also considering IP as the basis for TV broadcasts and\
   further services.  The program/content descriptions are referred to\
   as Internet Media Guides (IMGs) and can be viewed as a generalization\
   of Electronic Program Guides (EPGs) and multimedia session\
   descriptions.\
\
   An Internet Media Guide (IMG) has a structured collection of\
   multimedia session descriptions expressed using SDP, SDPng [7], or\
   some similar session description format.  This is used to describe a\
   set of multimedia services (e.g., television program schedules,\
   content delivery schedules) but may also refer to other networked\
   resources including web pages.  IMGs provide the envelope for\
   metadata formats and session descriptions defined elsewhere with the\
   aim of facilitating structuring, versioning, referencing,\
   distributing, and maintaining (caching, updating) such information.\
\
   The IMG metadata may be delivered to a potentially large audience,\
   who uses it to join a subset of the sessions described, and who may\
   need to be notified of changes to this information.  Hence, a\
   framework for distributing IMG metadata in various different ways is\
   needed to accommodate the needs of different audiences: For\
   traditional broadcast-style scenarios, multicast-based (push)\
   distribution of IMG metadata needs to be supported.  Where no\
   multicast is available, unicast-based push is required, too.\
\
\
\
Nomura, et al.               Informational                      [Page 3]\
\
RFC 4473     Requirements for Internet Media Guides (IMGs)      May 2006\
\
\
   Furthermore, IMG metadata may need to be retrieved interactively,\
   similar to web pages (e.g., after rebooting a system or when a user\
   is browsing after network connectivity has been re-established).\
   Finally, IMG metadata may be updated as time elapses because content\
   described in the guide may be changed: for example, the airtime of an\
   event such as a concert or sports event may change, possibly\
   affecting the airtime of subsequent media.  This may be done by\
   polling the IMG sender as well as by asynchronous change\
   notifications.\
\
   Furthermore, any Internet host can be a sender of content and thus an\
   IMG sender.  Some of the content sources and sinks may only be\
   connected to the Internet sporadically.  Also, a single human user\
   may use many different devices to access metadata.  Thus, we envision\
   that IMG metadata can be sent and received by, among others, cellular\
   phones, Personal Digital Assistants (PDAs), personal computers,\
   streaming video servers, set-top boxes, video cameras, and Digital\
   Video Recorders (DVRs), and that the data be carried across arbitrary\
   types of link layers, including bandwidth-constrained mobile\
   networks.  However, generally we expect IMG senders to be well-\
   connected hosts.\
\
   Finally, with many potential senders and receivers, different types\
   of networks, and presumably numerous service providers, IMG metadata\
   may need to be combined, split, filtered, augmented, modified, etc.,\
   on their way from the sender(s) to the receiver(s) to provide the\
   ultimate user with a suitable selection of multimedia services\
   according to her preferences, subscriptions, location, and context\
   (e.g., devices, access networks).\
\
1.2.  Scope of This Document\
\
   This document defines requirements that Internet Media Guide\
   mechanisms must satisfy in order to deliver IMG metadata to a\
   potentially large audience.  Since IMGs can describe many kinds of\
   multimedia content, IMG methods are generally applicable to several\
   scenarios.\
\
   In considering wide applicability, this document provides the problem\
   statement and discusses existing mechanisms in this area.  Then\
   several use case scenarios for IMGs are explained including\
   descriptions of how IMG metadata and IMG delivery mechanisms\
   contribute to these scenarios.  Following this, this document\
   provides general requirements that are independent of any transport\
   layer mechanism and application, such as delivery properties,\
   reliability, and IMG descriptions.\
\
\
\
\
\
Nomura, et al.               Informational                      [Page 4]\
\
RFC 4473     Requirements for Internet Media Guides (IMGs)      May 2006\
\
\
   This document reflects investigating work on delivery mechanisms for\
   IMGs and generalizing work on session announcement and initiation\
   protocols, especially in the field of the MMUSIC working group (SAP,\
   SIP [8], SDP).\
\
2.  Terminology\
\
   The key words "MUST", "MUST NOT", "REQUIRED", "SHALL", "SHALL NOT",\
   "SHOULD", "SHOULD NOT", "RECOMMENDED", "MAY", and "OPTIONAL" in this\
   document are to be interpreted as described in RFC 2119 [1].\
\
2.1.  New Terms\
\
   Internet Media Guide (IMG): IMG is a generic term used to describe\
         the formation, delivery, and use of IMG metadata.  The\
         definition of the IMG is intentionally left imprecise.\
\
   IMG Element: The smallest atomic element of metadata that can be\
         transmitted separately by IMG operations and referenced\
         individually from other IMG elements.\
\
   IMG Metadata: A set of metadata consisting of one or more IMG\
         elements.  IMG metadata describes the features of multimedia\
         content used to enable selection of and access to media\
         sessions containing content.  For example, metadata may consist\
         of the URI, title, airtime, bandwidth needed, file size, text\
         summary, genre, and access restrictions.\
\
   IMG Delivery: The process of exchanging IMG metadata in terms of both\
         large-scale and atomic data transfers.\
\
   IMG Sender: An IMG sender is a logical entity that sends IMG metadata\
         to one or more IMG receivers.\
\
   IMG Receiver: An IMG receiver is a logical entity that receives IMG\
         metadata from an IMG sender.\
\
   IMG Transceiver: An IMG transceiver combines an IMG receiver and\
         sender.  It may modify received IMG metadata or merge IMG\
         metadata received from several different IMG senders.\
\
   IMG Operation: An atomic operation of an IMG transport protocol, used\
         between IMG sender(s) and IMG receiver(s) for the delivery of\
         IMG metadata and for the control of IMG sender(s)/receiver(s).\
\
   IMG Transport Protocol: A protocol that transports IMG metadata from\
         an IMG sender to IMG receiver(s).\
\
\
\
\
Nomura, et al.               Informational                      [Page 5]\
\
RFC 4473     Requirements for Internet Media Guides (IMGs)      May 2006\
\
\
   IMG Transport Session: An association between an IMG sender and one\
         or more IMG receivers within the scope of an IMG transport\
         protocol.  An IMG transport session involves a time-bound\
         series of IMG transport protocol interactions that provide\
         delivery of IMG metadata from the IMG sender to the IMG\
         receiver(s).\
\
3.  Problem Statement\
\
   As we enumerate the requirements for IMGs, it will become clear that\
   they are not fully addressed by the existing protocols.  The\
   "Framework for the Usage of Internet Media Guides" [9] discusses\
   about these issues in more detail.\
\
   The MMUSIC working group has long been investigating content, media\
   and service information delivery mechanisms, and protocols, and has\
   itself produced the Session Announcement Protocol (SAP), the Session\
   Description Protocol (SDP), and the Session Initiation Protocol\
   (SIP).  SDP is capable of describing multimedia sessions (i.e.,\
   content in a wider sense) by means of limited descriptive information\
   intended for human perception plus transport, scheduling information,\
   and codecs and addresses for setting up media sessions.  SIP and SAP\
   are protocols to distribute these session descriptions.\
\
   However, we perceive a lack of a standard solution for scalable IMG\
   delivery mechanism in the number of receivers with consistency of IMG\
   metadata between an IMG sender and IMG receiver for both bi-\
   directional and unidirectional transport.  With increased service\
   dynamics and complexity, there is an increased requirement for\
   updates to these content descriptions.\
\
   HTTP [10] is a well-known information retrieval protocol using bi-\
   directional transport and is widely used to deliver web-based content\
   descriptions to many hosts.  However, it has well-recognized\
   limitations of scalability in the number of HTTP clients since it\
   relies on the polling mechanism to keep information consistent\
   between the server and client.\
\
   SAP [3] is an announcement protocol that distributes session\
   descriptions via multicast.  It does not support prioritization or\
   fine-grained metadata selection and update notifications, as it\
   places restrictions on metadata payload size and always sends the\
   whole metadata.  It requires a wide-area multicast infrastructure for\
   it to be deployable beyond a local area network.\
\
\
\
\
\
\
\
Nomura, et al.               Informational                      [Page 6]\
\
RFC 4473     Requirements for Internet Media Guides (IMGs)      May 2006\
\
\
   SIP [8] and SIP-specific event notifications [11] can be used to\
   notify subscribers of the update of IMG metadata for bi-directional\
   transport.  However, it is necessary to define an event package for\
   IMGs.\
\
   We also perceive a lack of standard solution for flexible content\
   descriptions to support a multitude of application-specific metadata\
   and associated data models with a different amount of detail and\
   different target audiences.\
\
   SDP [2] has a text-encoded syntax to specify multimedia sessions for\
   announcements and invitations.  It is primarily intended to describe\
   client capability requirements and enable client application\
   selection.  Although SDP is extensible, it has limitations such as\
   structured extensibility and capability to reference properties of a\
   multimedia session from the description of another session.\
\
   These can mostly be overcome by the XML-based SDPng [7] -- which is\
   intended for both two-way negotiation and unidirectional delivery --\
   or similar content description mechanisms.  Since SDPng addresses\
   multiparty multimedia conferences, it would be necessary to extend\
   the XML schema in order to describe general multimedia content.\
\
4.  Use Cases Requiring IMGs\
\
4.1.  Connectivity-based Use Cases\
\
4.1.1.  IP Datacast to a Wireless Receiver\
\
   IP Datacast is the delivery of IP-based services over broadcast\
   radio.  Internet content delivery is therefore unidirectional in this\
   case.  However, there can be significant benefits from being able to\
   provide rich media one-to-many services to such receivers.\
\
   There are two main classes of receiver in this use case: fixed\
   mains-powered and mobile battery-powered.  Both of these are affected\
   by radio phenomena and so robust, or error-resilient, delivery is\
   important.  Carouselled metadata transfer (cyclically repeated with a\
   fixed bandwidth) provides a base level of robustness for an IP\
   datacast-based announcement system, although the design of\
   carouselled transfer should enable battery-powered receivers to go\
   through periods of sleep to extend their operational time between\
   charges.  Insertion of Forward Error Correction (FEC) data into\
   metadata announcements improves error resilience, and reordering\
   (interleaving) data blocks further increases tolerance to burst\
   errors.\
\
\
\
\
\
Nomura, et al.               Informational                      [Page 7]\
\
RFC 4473     Requirements for Internet Media Guides (IMGs)      May 2006\
\
\
   To enable receivers to more accurately specify the metadata they are\
   interested in, the unidirectional delivery may be distributed between\
   several logical channels.  This is so that a receiver needs only\
   access the channels of interest and thus can reduce the amount of\
   time, storage, and CPU resources needed for processing the IP data.\
   Also, hierarchical channels enable receivers to subscribe to a\
   (possibly well-known) root multicast channel/group and progressively\
   access only those additional channels based on metadata in parent\
   channels.\
\
   In some cases, the receiver may have multiple access interfaces\
   adding bi-directional communications capability.  This enables a\
   multitude of options, but most important, it enables NACK-based\
   reliability and the individual retrieval of missed or not-multicast\
   sets of metadata.\
\
   Thus, essential IMG features in this case include the following:\
   robust unidirectional delivery (with optional levels of reliability\
   including "plug-in FEC" supported by a transport layer protocol),\
   which implies easily identifiable segmentation of delivery data to\
   make FEC, carousel, interleaving, and other schemes possible;\
   effective identification of metadata sets (probably uniquely) to\
   enable more efficient use of multicast and unicast retrieval over\
   multiple access systems regardless of the parts of metadata and\
   application-specific extensions in use; and prioritization of\
   metadata, which can (for instance) be achieved by spreading it\
   between channels and allocating/distributing bandwidth accordingly.\
\
   Furthermore, some cases require IMG metadata authentication and some\
   group security/encryption and supporting security message exchanges\
   (out of band from the IMG multicast sessions).\
\
4.1.2.  Regular Fixed Dial-up Internet Connection\
\
   Dial-up connections tend to be reasonably slow (<56 kbps in any\
   case), and thus large data transfers are less feasible, especially\
   during an active application session (such as a file transfer\
   described by IMG metadata).  They can also be intermittent,\
   especially if a user is paying for the connected time, or connected\
   through a less reliable exchange.  Thus, this favors locally stored\
   IMG metadata over web-based browsing, especially where parts of the\
   metadata change infrequently.  There may be no service provider\
   preference over unicast and multicast transport for small and medium\
   numbers of users as the last-mile dial-up connection limits per-user\
   congestion, and a user may prefer the more reliable option (unicast\
   unless reliable multicast is provided).\
\
\
\
\
\
Nomura, et al.               Informational                      [Page 8]\
\
RFC 4473     Requirements for Internet Media Guides (IMGs)      May 2006\
\
\
4.1.3.  Broadband Always-on Fixed Internet Connection\
\
   Typically, bandwidth is less of an issue to a broadband user and\
   unicast transport, such as using query-response methods, may be\
   typical for a PC user.  If a system were only used in this context,\
   with content providers, ISPs, and users having no other requirements,\
   then web-based browsing may be equally suitable.  However, broadband\
   users sharing a local area network, especially wireless, may benefit\
   more from local storage features than on-line browsing, especially if\
   they have intermittent Internet access.\
\
   Some services on broadband, such as live media broadcasting, benefit\
   from multicast transport for streaming media because of scalability.\
   In the cases where multicast transport is already available, it is\
   convenient for a sender and receiver to retrieve IMG metadata over\
   multicast transport.  Thus, broadband users may be forced to retrieve\
   IMG metadata over multicast if backbone operators require this to\
   keep system-wide bandwidth usage feasible.\
\
4.2.  Content-orientated Use Cases\
\
   IMGs will be able to support a very wide range of use cases for\
   enabling content/media delivery.  The following few sections just\
   touch the surface of what is possible and are intended to provide an\
   understanding of the scope and type of IMG usage.  Many more examples\
   may be relevant, for instance, those detailed in [12].  There are\
   several unique features of IMGs that set them apart from related\
   application areas such as Service Location Protocol (SLP) based\
   service location discovery, Lightweight Directory Access Protocol\
   (LDAP) based indexing services, and search engines such as Google.\
   Features unique to IMGs include the following:\
\
      o  IMG metadata is generally time-related\
\
      o  There are timeliness requirements in the delivery of IMG\
         metadata\
\
      o  IMG metadata may be updated as time elapses or when an event\
         arises\
\
4.2.1.  TV and Radio Program Delivery\
\
   A sender of audio/video streaming content can use the IMG metadata to\
   describe the scheduling and other properties of audio/video sessions\
   and events within those sessions, such as individual TV and radio\
   programs and segments within those programs.  IMG metadata describing\
   audio/video streaming content could be represented in a format\
\
\
\
\
Nomura, et al.               Informational                      [Page 9]\
\
RFC 4473     Requirements for Internet Media Guides (IMGs)      May 2006\
\
\
   similar to that of a TV guide in newspapers, or an Electronic Program\
   Guide available on digital TV receivers.\
\
   TV and radio programs can be selected for reception either manually\
   by the end-user or automatically based on the content descriptions\
   and the preferences of the user.  The received TV and radio content\
   can be either presented in real time or recorded for later\
   consumption.  There may be changes in the scheduling of a TV or a\
   radio program, possibly affecting the transmission times of\
   subsequent programs.  IMG metadata can be used to notify receivers of\
   such changes, enabling users to be prompted or recording times to be\
   adjusted.\
\
4.2.2.  Media Coverage of a Live Event\
\
   The media coverage of a live event such as a rock concert or a sports\
   event is a special case of regular TV/radio programming.  There may\
   be unexpected changes in the scheduling of a live event, or the event\
   may be unscheduled to start with (such as breaking news).  In\
   addition to audio/video streams, textual information relevant to the\
   event (e.g., statistics of the players during a football match) may\
   be sent to user terminals.  Different transport modes or even\
   different access technologies can be used for the different media:\
   for example, a unidirectional datacast transport could be used for\
   the audio/video streams and an interactive cellular connection for\
   the textual data.  IMG metadata should enable terminals to discover\
   the availability of different media used to cover a live event.\
\
4.2.3.  Distance Learning\
\
   IMG metadata could describe compound sessions or services enabling\
   several alternative interaction modes between the participants.  For\
   example, the combination of one-to-many media streaming, unicast\
   messaging, and downloading of presentation material could be useful\
   for distance learning.\
\
4.2.4.  Multiplayer Gaming\
\
   Multiplayer games are an example of real-time multiparty\
   communication sessions that could be advertised using IMGs.  A gaming\
   session could be advertised either by a dedicated server or by the\
   terminals of individual users.  A user could use IMGs to learn of\
   active multiplayer gaming sessions, or advertise the user's interest\
   in establishing such a session.\
\
\
\
\
\
\
\
Nomura, et al.               Informational                     [Page 10]\
\
RFC 4473     Requirements for Internet Media Guides (IMGs)      May 2006\
\
\
4.2.5.  File Distribution\
\
   IMGs support the communication of file delivery session properties,\
   enabling the scheduled delivery or synchronization of files between a\
   number of hosts.  The received IMG metadata could be subsequently\
   used by any application (also outside the scope of IMGs), for\
   example, to download a file with a software update.  IMG metadata can\
   provide a description to each file in a file delivery session,\
   assisting users or receiving software in selecting individual files\
   for reception.\
\
   For example, when a content provider wants to distribute a large\
   amount of data in file format to thousands of clients, the content\
   provider can use IMG metadata to schedule the delivery effectively.\
\
   Since IMG metadata can describe time-related data for each receiver,\
   the content provider can schedule delivery time for each receiver.\
   This can save network bandwidth and delivery capacity of senders.  In\
   addition, IMG metadata can be used to consistency check, and thus\
   synchronize, a set of files between a sender host and receiver host,\
   when those files change as time elapses.\
\
4.2.6.  Coming-release and Pre-released Content\
\
   IMG metadata can be used to describe items of content before the\
   details of their final release are known.  A user may be interested\
   in coming content (a new movie or software title where some aspects\
   of the content description are known in advance) and so subscribe to\
   an information service that notifies the user of changes to metadata\
   describing that content.  Thus, as the coming release (or pre-\
   releases, e.g., as movie trailers or software demos) become\
   available, the IMG metadata changes and the user is notified of this\
   change.  For example, the user could see an announcement of a movie\
   that will be released sometime in the next few months, and configure\
   the user's terminal to receive and record any trailers or promotional\
   material as they become available.\
\
5.  Requirements\
\
5.1.  General Requirements\
\
5.1.1.  Independence of IMG Operations from IMG Metadata\
\
   REQ GEN-1: Carrying different kinds of IMG metadata format and\
   different IMG metadata formats in the IMG message body MUST be\
   allowed.\
\
\
\
\
\
Nomura, et al.               Informational                     [Page 11]\
\
RFC 4473     Requirements for Internet Media Guides (IMGs)      May 2006\
\
\
   REQ GEN-2: Delivery mechanisms SHOULD support many different\
   applications' specific metadata formats to keep the system\
   interoperable with existing applications.\
\
   This provides flexibility in selecting/designing an IMG transport\
   protocol suited to various scenarios.\
\
5.1.2.  Multiple IMG Senders\
\
   REQ GEN-3: IMG receivers MUST be allowed to communicate with any\
   number of IMG senders simultaneously.\
\
   This might lead to receiving redundant IMG metadata describing the\
   same items; however, it enables the IMG receiver access to more IMG\
   metadata than may be available from a single IMG sender.  This also\
   provides flexibility for the IMG transport protocols and does not\
   preclude a mechanism to solve inconsistency among IMG metadata due to\
   multiple IMG senders.  This document assumes that a typical IMG\
   environment will involve many more IMG receivers than IMG senders and\
   that IMG senders are continually connected for the duration of\
   interest (rather than intermittently connected).\
\
5.1.3.  Modularity\
\
   REQ GEN-4: The IMG delivery mechanisms MUST allow the combination of\
   several IMG operations.\
\
   This is for the purpose of extending functionality (e.g., several or\
   one protocol(s) to provide all the needed operations).  Applications\
   can select an appropriate operation set to fulfill their purpose.\
\
5.2.  Delivery Properties\
\
   This section describes general performance requirements based on the\
   assumption that the range of IMG usage shall be important.  However,\
   note that requirements for delivery properties may vary based on the\
   usage scenario, and thus some limited-use implementations place less\
   importance on some requirements.\
\
   For example, it is clear that a multicast transport may provide more\
   scalable delivery than a unicast transport; however, scalability\
   requirements do not preclude the unicast transport mechanisms.  In\
   this sense, scalability is always important for the protocols\
   irrespective of transport mechanisms.\
\
\
\
\
\
\
\
Nomura, et al.               Informational                     [Page 12]\
\
RFC 4473     Requirements for Internet Media Guides (IMGs)      May 2006\
\
\
5.2.1.  Scalability\
\
   REQ DEL-1: The IMG system MUST be scalable to large numbers of\
   messages, so as to allow design and use of delivery mechanisms that\
   will not fail in delivering up-to-date information under huge numbers\
   of transactions and massive quantities of IMG metadata.\
\
   REQ DEL-2: IMGs SHOULD provide a method to prevent an IMG sender from\
   sending unnecessary IMG metadata that have been stored or deleted in\
   IMG receivers.\
\
   REQ DEL-3: The protocol MUST be scalable to very large audience sizes\
   requiring IMG delivery.\
\
5.2.2.  Support for Intermittent Connectivity\
\
   REQ DEL-4: The system MUST enable IMG receivers with intermittent\
   access to network resources (connectivity) to receive and adequately\
   maintain sufficient IMG metadata.\
\
   This allows intermittent access to save power where there is no need\
   to keep communications links powered up while they are sitting idle.\
   For instance, in this situation, periodic bursts of notifies or a\
   fast cycling update carousel allow hosts to wake up for short periods\
   of time and still be kept up-to-date.  This can be beneficial for IMG\
   receivers with sporadic connections to the fixed Internet, but is\
   critical in the battery-powered wireless Internet.\
\
   The implication of intermittent connectivity is that immediate\
   distribution of changes becomes infeasible and so managing data\
   consistency should be focused on the timely delivery of data.\
\
5.2.3.  Congestion Control\
\
   REQ DEL-5: Internet-friendly congestion control MUST be provided for\
   use on the public Internet.\
\
   REQ DEL-6: An IMG entity SHOULD invalidate the IMG metadata item when\
   an IMG metadata item has lifetime information and its lifetime is\
   over.  This will lessen the need for notifications of updates from\
   the IMG sender to the IMG receiver to invalidate the item and may\
   help in reducing load.\
\
5.2.4.  Sender- and Receiver-Driven Delivery\
\
   REQ DEL-7: The system MUST be flexible in choosing sender-driven,\
   receiver-driven, or both delivery schemes.\
\
\
\
\
Nomura, et al.               Informational                     [Page 13]\
\
RFC 4473     Requirements for Internet Media Guides (IMGs)      May 2006\
\
\
   Sender-driven delivery achieves high scalability without interaction\
   between the IMG sender and receiver.\
\
   In contrast, receiver-driven delivery provides on-demand delivery for\
   IMG receivers.  Since an IMG sender's complete IMG metadata may be a\
   very large amount of data, the IMG receiver needs to be able to\
   access the guide when convenient (e.g., when sufficient network\
   bandwidth is available to the IMG receiver).\
\
5.3.  Customized IMGs\
\
   REQ CUS-1: The system MUST allow delivery of customized IMG metadata.\
\
   The IMG receiver may require a subset of all the IMG metadata\
   available according to their preferences (type of content, media\
   description, appropriate age group, etc.) and configuration.\
\
   The IMG receiver might send its preferences in the IMG operations\
   that can specify user-specific IMG metadata to be delivered.  These\
   preferences could consist of filtering rules.  When receiving these\
   messages, the IMG sender might respond with appropriate messages\
   carrying a subset of IMG metadata that matches the IMG receiver's\
   preferences.\
\
   This mechanism can reduce the amount of IMG metadata delivered from\
   the IMG sender to IMG receiver, and consequently it can save the\
   resource consumption on the IMG entities and networks.  It is\
   typically useful in unicast cases and also beneficial in multicast\
   cases where an IMG sender distributes the same IMG metadata to\
   interested IMG receivers at the same time.\
\
   For multicast and unicast cases where the IMG sender does not provide\
   customized IMG metadata, the IMG receiver could receive all IMG\
   metadata transmitted on the channels that the IMG receiver has\
   joined.  However, it may select and filter the IMG metadata to get\
   customized IMG metadata by its preferences, and thus drop unwanted\
   metadata immediately upon reception.\
\
   Customizing metadata might be achieved by changing the IMG\
   descriptions sent and IMG receivers and/or changing the delivery\
   properties (channels used).\
\
   Note that customization and scalability are only somewhat exclusive.\
   Systems providing an IMG receiver to an IMG sender request-based\
   customization will be generally less scalable to massive IMG receiver\
   populations than those without this return signaling technique.\
   Thus, customization, as with any feature that affects scalability,\
   should be carefully designed for the intended application, and it may\
\
\
\
Nomura, et al.               Informational                     [Page 14]\
\
RFC 4473     Requirements for Internet Media Guides (IMGs)      May 2006\
\
\
   not be possible that a one-size-fits-all solution for customization\
   would meet the scalability requirements for all applications and\
   deployment cases.\
\
5.4.  Reliability\
\
5.4.1.  Managing Consistency\
\
   IMG metadata tends to change as time elapses; as new content is\
   added, the old IMG metadata stored in the IMG receiver becomes\
   unavailable, and the parameters of the existing IMG metadata are\
   changed.\
\
   REQ REL-1: The system MUST manage IMG metadata consistency.\
\
   Either the IMG sender can simply make updates available\
   (unsynchronized), or the IMG sender and receiver can interact to keep\
   their copies of the IMG metadata synchronized.\
\
   In the unsynchronized model, the IMG sender does not know whether a\
   particular IMG receiver has an up-to-date copy of the IMG metadata.\
\
   In the synchronized model, updating a cached copy of the IMG metadata\
   is necessary to control consistency when the IMG sender or receiver\
   could not communicate for a while.  In this case, the IMG sender or\
   receiver may need to confirm its consistency by IMG operations.\
\
   REQ REL-2: Since IMG metadata can change at any time, IMG receivers\
   SHOULD be notified of such changes.\
\
   Fulfilling this requirement needs to be compatible with the\
   scalability requirements for the number of IMG receivers and the\
   consistency of metadata.\
\
   Depending on the size of the IMG metadata, the interested party may\
   want to defer retrieving the actual information.  The change\
   notification should be addressed to a logical user (or user group),\
   rather than a host, since users may change devices.\
\
   Note that depending on the deployment environment and application\
   specifics, the level of acceptable inconsistency varies.  Thus, this\
   document does not define inconsistency as specific time and state\
   differences between IMG metadata stored in an IMG sender and IMG\
   metadata stored in an IMG receiver.\
\
   In general, the consistency of metadata for content and media is more\
   important immediately prior to and during the media's session(s).\
   Hosts that forward (or otherwise resend) metadata may not tolerate\
\
\
\
Nomura, et al.               Informational                     [Page 15]\
\
RFC 4473     Requirements for Internet Media Guides (IMGs)      May 2006\
\
\
   inconsistencies because delivering out-of-date data is both\
   misleading and bandwidth inefficient.\
\
5.4.2.  Reliable Message Exchange\
\
   REQ REL-4: An IMG transport protocol MUST support reliable message\
   exchange.\
\
   The extent to which this could result in 100% error-free delivery to\
   100% of IMG receivers is a statistical characteristic of the\
   protocols used.  Usage of reliable IMG delivery mechanisms is\
   expected to depend on the extent to which underlying networks provide\
   reliability and, conversely, introduce errors.  Note that some\
   deployments of IMG transport protocols may not aim to provide perfect\
   reception to all IMG receivers in all possible cases.\
\
5.5.  IMG Descriptions\
\
   REQ DES-1: IMG metadata MUST be interoperable over any IMG transport\
   protocol, such that an application receiving the same metadata over\
   any one (or more) of several network connections and/or IMG transport\
   protocols will interpret the metadata in exactly the same way.  (This\
   also relates to the 'Independence of IMG Operations from IMG\
   Metadata' requirements.)\
\
   REQ DES-2: IMG delivery MUST enable the carriage of any format of\
   application-specific metadata.\
\
   Thus, the system will support the description of many kinds of\
   multimedia content, without the need for a single homogeneous\
   metadata syntax for all uses (which would be infeasible anyway).\
   This is essential for environments using IMG systems to support many\
   kinds of multimedia content and to achieve wide applicability.\
\
   REQ DES-3: Whereas specific applications relying on IMGs will need to\
   select one or more specific application-specific metadata formats\
   (standard, syntax, etc.), the IMG system MUST be independent of this\
   (it may be aware, but it will operate in the same way for all).\
\
   Thus, a metadata transfer envelope format that is uniform across all\
   different application-specific IMG metadata formats is needed.  The\
   envelope would reference (point to) or carry (as payload) some\
   application-specific metadata, and the envelope would support the\
   maintenance of the application-specific metadata, which may also\
   serve the metadata relationships determined by the data model(s)\
   used.  The envelope would not need to be aware of the data model(s)\
   in use.\
\
\
\
\
Nomura, et al.               Informational                     [Page 16]\
\
RFC 4473     Requirements for Internet Media Guides (IMGs)      May 2006\
\
\
   REQ DES-4: IMG metadata MUST be structured to enable fragmentation\
   for efficient delivery.\
\
   This is intended to ensure that an IMG sender with more than a\
   trivial knowledge of metadata is able to deliver only part of its\
   (and the global) complete IMG metadata knowledge.  (For instance, a\
   trivial quantity of knowledge could be a single SDP description.)  In\
   general, the resolution of this fragmentation will be very much\
   dependent on the optimal delivery of a deployment, although some\
   metadata syntaxes will inherently affect the sensible lower limit for\
   a single element/fragment.\
\
   REQ DES-5: A metadata transfer envelope MUST be defined to include\
   essential parameters.\
\
   Examples of essential parameters are those that allow the metadata in\
   question to be uniquely identified and updated by new versions of the\
   same metadata.\
\
   REQ DES-6: It SHALL be possible to deduce the metadata format via the\
   metadata transfer envelope.\
\
   REQ DES-7: IMG senders SHALL use a metadata transfer envelope for\
   each IMG metadata transfer.\
\
   Thus, it will even be possible to describe relationships between\
   syntactically dissimilar application-specific formats within the same\
   body of IMG metadata knowledge.  (For instance, a data model could be\
   instantiated using both SDP and SDPng.)\
\
   REQ DES-8: IMG metadata SHOULD support the description of differences\
   between an updated version and an old version of IMG metadata when\
   the IMG delivery mechanism carries updated IMG metadata and those\
   differences are considerably little (e.g., by providing a 'delta' of\
   the two versions; this also relates the delivery property\
   requirements for congestion control in Section 5.2.3).\
\
6.  Security Considerations\
\
   Internet Media Guides are used to convey information about multimedia\
   resources from one or more IMG senders across one or more\
   intermediaries to one or more IMG receivers.  IMG metadata may be\
   pushed to the IMG receivers or interactively retrieved by them.  IMGs\
   provide metadata as well as scheduling and rendezvous information\
   about multimedia resources, and so on, and requests for IMG metadata\
   may contain information about the requesting users.\
\
\
\
\
\
Nomura, et al.               Informational                     [Page 17]\
\
RFC 4473     Requirements for Internet Media Guides (IMGs)      May 2006\
\
\
   The information contained in IMG metadata as well as the operations\
   related to IMGs should be secured to avoid forged information,\
   misdirected users, and spoofed IMG senders, for example, and to\
   protect user privacy.\
\
   The remainder of this section addresses the security requirements for\
   IMGs.\
\
6.1.  IMG Authentication and Integrity\
\
   IMG metadata and its parts need to be protected against unauthorized\
   alteration/addition/deletion on the way.  Their originator needs to\
   be authenticated.\
\
   REQ AUT-1: It MUST be possible to authenticate the originator of a\
   set of IMG metadata.\
\
   REQ AUT-2: It MUST be possible to authenticate the originator of a\
   subpart of IMG metadata (e.g., a delta or a subset of the\
   information).\
\
   REQ AUT-3: It MUST be possible to validate the integrity of IMG\
   metadata.\
\
   REQ AUT-4: It MUST be possible to validate the integrity of a subpart\
   of IMG metadata (e.g., a delta or a subset of the information).\
\
   REQ AUT-5: It MUST be possible to separate or combine individually\
   authenticated pieces of IMG metadata (e.g., in an IMG transceiver)\
   without invalidating the authentication.\
\
   REQ AUT-6: It MUST be possible to validate the integrity of an\
   individually authenticated piece of IMG metadata even after this\
   piece has been separated from other pieces of IMG metadata and\
   combined with other pieces to form new IMG metadata.\
\
   REQ AUT-7: It MUST be possible to authenticate the originator of an\
   IMG operation.\
\
   REQ AUT-8: It MUST be possible to validate the integrity of any\
   contents of an IMG operation (e.g., the subscription or inquiry\
   information).\
\
\
\
\
\
\
\
\
\
Nomura, et al.               Informational                     [Page 18]\
\
RFC 4473     Requirements for Internet Media Guides (IMGs)      May 2006\
\
\
6.2.  Privacy\
\
   Customized IMG metadata and IMG metadata delivered by notification to\
   individual users may reveal information about the habits and\
   preferences of a user and may thus deserve confidentiality\
   protection, even though the information itself is public.\
\
   REQ PRI-1: It MUST be possible to keep user requests to subscribe to\
   or retrieve certain (parts of) IMG metadata confidential.\
\
   REQ PRI-2: It MUST be possible to keep IMG metadata, pieces of IMG\
   metadata, or pointers to IMG metadata delivered to individual users\
   or groups of users confidential.\
\
   REQ PRI-3: It SHOULD be possible to ensure this confidentiality end-\
   to-end, that is, to prevent intermediaries (such as IMG transceivers)\
   from accessing the contained information.\
\
6.3.  Access Control for IMGs\
\
   Some IMG metadata may be freely available, while access to other IMG\
   metadata may be restricted to closed user groups (e.g., paying\
   subscribers).  Also, different parts of IMG metadata may be protected\
   at different levels: for example, metadata describing a media session\
   may be freely accessible, while rendezvous information to actually\
   access the media session may require authorization.\
\
   REQ ACC-1: It MUST be possible to authorize user access to IMG\
   metadata.\
\
   REQ ACC-2: It MUST be possible to authorize access of users to pieces\
   of IMG metadata (delta information, subparts, pointers).\
\
   REQ ACC-3: It MUST be possible to require different authorization for\
   different parts of the same IMG metadata.\
\
   REQ ACC-4: It MUST be possible to access selected IMG metadata\
   anonymously.\
\
   REQ ACC-5: It MUST be possible for an IMG receiver to choose not to\
   receive (parts of) IMG metadata in order to avoid being identified by\
   the IMG sender.\
\
   REQ ACC-6: It SHOULD be possible for an IMG transceiver to select\
   suitable authorization methods that are compatible between both IMG\
   senders and IMG receivers it interacts with.\
\
\
\
\
\
Nomura, et al.               Informational                     [Page 19]\
\
RFC 4473     Requirements for Internet Media Guides (IMGs)      May 2006\
\
\
   REQ ACC-7: It MAY be possible for IMG senders to require certain\
   authorization that cannot be modified by intermediaries.\
\
6.4.  Denial-of-Service (DOS) Attacks\
\
   Retrieving or distributing IMG metadata may require state in the IMG\
   senders, transceivers, and/or receivers for the respective IMG\
   transport sessions.  Attackers may create large numbers of sessions\
   with any of the above IMG entities to disrupt regular operation.\
\
   REQ DOS-1: IMG operations SHOULD be authenticated.\
\
   REQ DOS-2: It SHOULD be possible to avoid DoS attacks that build up\
   session state in IMG entities to exhaust their resources.\
\
   REQ DOS-3: It SHOULD be possible to avoid DoS attacks that exhaust\
   resources of IMG entities by flooding them with IMG metadata.\
\
   As an example, two potential solutions that may be considered are\
   running an IMG entity in stateless mode or identification and\
   discarding of malicious packets by an IMG entity.\
\
6.5.  Replay Attacks\
\
   IMG metadata disseminated by an IMG sender or an IMG transceiver may\
   be updated, be deleted, or lose validity over time for some other\
   reasons.  Replaying outdated IMG metadata needs to be prevented.\
\
   Furthermore, replay attacks may also apply to IMG operations (rather\
   than just their payload).  Replaying operations also needs to be\
   prevented.\
\
   REQ REP-1: IMG metadata MUST be protected against partial or full\
   replacement of newer ("current") versions by older ones.\
\
   In a system with multiple senders, it may not be feasible to prevent\
   some senders from delivering older versions of metadata than others -\
   as a result of imperfect sender-sender data consistency.  Thus,\
   replay attacks and delivery of inconsistent data require that an IMG\
   receiver verifies that the IMG metadata is valid and reliable by\
   using some security mechanism(s) (e.g., authorization,\
   authentication, or integrity).\
\
   REQ REP-2: Mechanisms MUST be provided to mitigate replay attacks on\
   the IMG operations.\
\
\
\
\
\
\
Nomura, et al.               Informational                     [Page 20]\
\
RFC 4473     Requirements for Internet Media Guides (IMGs)      May 2006\
\
\
   The level of threat from replay attacks varies very much depending on\
   system scale and how well defined or open it is.  Thus, mitigating\
   replay attacks may lead to different solutions for different systems,\
   independent of the basic delivery method and metadata definitions.  A\
   system with multiple senders presents a more challenging scenario for\
   handling replay attacks.  As an example, bundling metadata with a\
   security mechanism is one potential solution.\
\
7.  Normative References\
\
   [1]  Bradner, S., "Key words for use in RFCs to Indicate Requirement\
        Levels", BCP 14, RFC 2119, March 1997.\
\
8.  Informative References\
\
   [2]  Handley, M. and V. Jacobson, "SDP: Session Description\
        Protocol", RFC 2327, April 1998.\
\
   [3]  Handley, M., Perkins, C., and E. Whelan, "Session Announcement\
        Protocol", RFC 2974, October 2000.\
\
   [4]  Session Directory, ftp://ftp.ee.lbl.gov/conferencing/sd/\
\
   [5]  Session Directory Tool, http://www-\
        mice.cs.ucl.ac.uk/multimedia/software/sdr/\
\
   [6]  Digital Video Broadcasting Project, http://www.dvb.org/\
\
   [7]  Kutscher, D., Ott, J., and C. Bormann, "Session description and\
        capability negotiation", Work in Progress, February 2005.\
\
   [8]  Rosenberg, J., Schulzrinne, H., Camarillo, G., Johnston, A.,\
        Peterson, J., Sparks, R., Handley, M., and E. Schooler, "SIP:\
        Session Initiation Protocol", RFC 3261, June 2002.\
\
   [9]  Nomura, Y., Walsh, R., Luoma, J-P., Asaeda, H., and H.\
        Schulzrinne, "Framework for the Usage of Internet Media Guides\
        (IMG)", RFC 4435, April 2006.\
\
   [10] Fielding, R., Gettys, J., Mogul, J., Frystyk, H., Masinter, L.,\
        Leach, P., and T. Berners-Lee, "Hypertext Transfer Protocol --\
        HTTP/1.1", RFC 2616, June 1999.\
\
   [11] Roach, A.B., "Session Initiation Protocol (SIP)-Specific Event\
        Notification", RFC 3265, June 2002.\
\
   [12] Quinn, B. and K. Almeroth, "IP Multicast Applications:\
        Challenges and Solutions", RFC 3170, September 2001.\
\
\
\
Nomura, et al.               Informational                     [Page 21]\
\
RFC 4473     Requirements for Internet Media Guides (IMGs)      May 2006\
\
\
9.  Acknowledgements\
\
   The authors would like to thank Hitoshi Asaeda, Gonzalo Camarillo,\
   Jean-Pierre Evain, Dirk Kutscher, Petri Koskelainen, Colin Perkins,\
   Toni Paila, and Magnus Westerlund for their excellent comments and\
   ideas on this work.\
\
Authors' Addresses\
\
   Yuji Nomura\
   Fujitsu Laboratories Ltd.\
   4-1-1 Kamikodanaka, Nakahara-ku, Kawasaki 211-8588\
   Japan\
\
   EMail: nom@flab.fujitsu.co.jp\
\
   Rod Walsh\
   Nokia Research Center\
   P.O. Box 100, FIN-33721 Tampere\
   Finland\
\
   EMail: rod.walsh@nokia.com\
\
   Juha-Pekka Luoma\
   Nokia Research Center\
   P.O. Box 100, FIN-33721 Tampere\
   Finland\
\
   EMail: juha-pekka.luoma@nokia.com\
\
   Joerg Ott\
   Helsinki University of Technology\
   Networking Laboratory\
   PO Box 3000\
   FIN-02015 TKK\
   Finland\
\
   EMail: jo@netlab.tkk.fi\
\
   Henning Schulzrinne\
   Dept. of Computer Science\
   Columbia University\
   1214 Amsterdam Avenue\
   New York, NY 10027\
   USA\
\
   EMail: schulzrinne@cs.columbia.edu\
\
\
\
\
Nomura, et al.               Informational                     [Page 22]\
\
RFC 4473     Requirements for Internet Media Guides (IMGs)      May 2006\
\
\
Full Copyright Statement\
\
   Copyright (C) The Internet Society (2006).\
\
   This document is subject to the rights, licenses and restrictions\
   contained in BCP 78, and except as set forth therein, the authors\
   retain all their rights.\
\
   This document and the information contained herein are provided on an\
   "AS IS" basis and THE CONTRIBUTOR, THE ORGANIZATION HE/SHE REPRESENTS\
   OR IS SPONSORED BY (IF ANY), THE INTERNET SOCIETY AND THE INTERNET\
   ENGINEERING TASK FORCE DISCLAIM ALL WARRANTIES, EXPRESS OR IMPLIED,\
   INCLUDING BUT NOT LIMITED TO ANY WARRANTY THAT THE USE OF THE\
   INFORMATION HEREIN WILL NOT INFRINGE ANY RIGHTS OR ANY IMPLIED\
   WARRANTIES OF MERCHANTABILITY OR FITNESS FOR A PARTICULAR PURPOSE.\
\
Intellectual Property\
\
   The IETF takes no position regarding the validity or scope of any\
   Intellectual Property Rights or other rights that might be claimed to\
   pertain to the implementation or use of the technology described in\
   this document or the extent to which any license under such rights\
   might or might not be available; nor does it represent that it has\
   made any independent effort to identify any such rights.  Information\
   on the procedures with respect to rights in RFC documents can be\
   found in BCP 78 and BCP 79.\
\
   Copies of IPR disclosures made to the IETF Secretariat and any\
   assurances of licenses to be made available, or the result of an\
   attempt made to obtain a general license or permission for the use of\
   such proprietary rights by implementers or users of this\
   specification can be obtained from the IETF on-line IPR repository at\
   http://www.ietf.org/ipr.\
\
   The IETF invites any interested party to bring to its attention any\
   copyrights, patents or patent applications, or other proprietary\
   rights that may cover technology that may be required to implement\
   this standard.  Please address the information to the IETF at\
   ietf-ipr@ietf.org.\
\
Acknowledgement\
\
   Funding for the RFC Editor function is provided by the IETF\
   Administrative Support Activity (IASA).\
\
\
\
\
\
\
\
Nomura, et al.               Informational                     [Page 23]\
\

doc 14
  field 0
    name titolo
    type string
    value rfc4471.txt
  field 1
    name contenuto
    type string
    value \
\
\
\
\
\
Network Working Group                                          G. Sisson\
Request for Comments: 4471                                     B. Laurie\
Category: Experimental                                           Nominet\
                                                          September 2006\
\
\
            Derivation of DNS Name Predecessor and Successor\
\
\
Status of This Memo\
\
   This memo defines an Experimental Protocol for the Internet\
   community.  It does not specify an Internet standard of any kind.\
   Discussion and suggestions for improvement are requested.\
   Distribution of this memo is unlimited.\
\
Copyright Notice\
\
   Copyright (C) The Internet Society (2006).\
\
Abstract\
\
   This document describes two methods for deriving the canonically-\
   ordered predecessor and successor of a DNS name.  These methods may\
   be used for dynamic NSEC resource record synthesis, enabling\
   security-aware name servers to provide authenticated denial of\
   existence without disclosing other owner names in a DNSSEC secured\
   zone.\
\
Table of Contents\
\
   1. Introduction ....................................................2\
   2. Notational Conventions ..........................................3\
   3. Derivations .....................................................3\
      3.1. Absolute Method ............................................3\
           3.1.1. Derivation of DNS Name Predecessor ..................3\
           3.1.2. Derivation of DNS Name Successor ....................4\
      3.2. Modified Method ............................................4\
           3.2.1. Derivation of DNS Name Predecessor ..................5\
           3.2.2. Derivation of DNS Name Successor ....................6\
   4. Notes ...........................................................6\
      4.1. Test for Existence .........................................6\
      4.2. Case Considerations ........................................7\
      4.3. Choice of Range ............................................7\
      4.4. Wild Card Considerations ...................................8\
      4.5. Possible Modifications .....................................8\
           4.5.1. Restriction of Effective Maximum DNS Name Length ....8\
           4.5.2. Use of Modified Method with Zones Containing\
\
\
\
Sisson & Laurie               Experimental                      [Page 1]\
\
RFC 4471           DNS Name Predecessor and Successor     September 2006\
\
\
                  SRV RRs .............................................8\
   5. Examples ........................................................9\
      5.1. Examples of Immediate Predecessors Using Absolute Method ..10\
      5.2. Examples of Immediate Successors Using Absolute Method ....14\
      5.3. Examples of Predecessors Using Modified Method ............19\
      5.4. Examples of Successors Using Modified Method ..............20\
   6. Security Considerations ........................................21\
   7. Acknowledgements ...............................................21\
   8. References .....................................................21\
      8.1. Normative References ......................................21\
      8.2. Informative References ....................................22\
\
1.  Introduction\
\
   One of the proposals for avoiding the exposure of zone information\
   during the deployment DNSSEC is dynamic NSEC resource record (RR)\
   synthesis.  This technique is described in [DNSSEC-TRANS] and\
   [RFC4470], and involves the generation of NSEC RRs that just span the\
   query name for non-existent owner names.  In order to do this, the\
   DNS names that would occur just prior to and just following a given\
   query name must be calculated in real time, as maintaining a list of\
   all possible owner names that might occur in a zone would be\
   impracticable.\
\
   Section 6.1 of [RFC4034] defines canonical DNS name order.  This\
   document does not amend or modify this definition.  However, the\
   derivation of immediate predecessor and successor, although trivial,\
   is non-obvious.  Accordingly, several methods are described here as\
   an aid to implementors and a reference to other interested parties.\
\
   This document describes two methods:\
\
   1.  An "absolute method", which returns the immediate predecessor or\
       successor of a domain name such that no valid DNS name could\
       exist between that DNS name and the predecessor or successor.\
\
   2.  A "modified method", which returns a predecessor and successor\
       that are more economical in size and computation.  This method is\
       restricted to use with zones consisting exclusively of owner\
       names that contain no more than one label more than the owner\
       name of the apex, where the longest possible owner name (i.e.,\
       one with a maximum length left-most label) would not exceed the\
       maximum DNS name length.  This is, however, the type of zone for\
       which the technique of online signing is most likely to be used.\
\
\
\
\
\
\
\
Sisson & Laurie               Experimental                      [Page 2]\
\
RFC 4471           DNS Name Predecessor and Successor     September 2006\
\
\
2.  Notational Conventions\
\
   The following notational conventions are used in this document for\
   economy of expression:\
\
   N: An unspecified DNS name.\
\
   P(N): Immediate predecessor to N (absolute method).\
\
   S(N): Immediate successor to N (absolute method).\
\
   P'(N): Predecessor to N (modified method).\
\
   S'(N): Successor to N (modified method).\
\
3.  Derivations\
\
   These derivations assume that all uppercase US-ASCII letters in N\
   have already been replaced by their corresponding lowercase\
   equivalents.  Unless otherwise specified, processing stops after the\
   first step in which a condition is met.\
\
   The derivations make reference to maximum label length and maximum\
   DNS name length; these are defined in Section 3.1 of [RFC1034] to be\
   63 and 255 octets, respectively.\
\
3.1.  Absolute Method\
\
3.1.1.  Derivation of DNS Name Predecessor\
\
   To derive P(N):\
\
   1.  If N is the same as the owner name of the zone apex, prepend N\
       repeatedly with labels of the maximum length possible consisting\
       of octets of the maximum sort value (e.g., 0xff) until N is the\
       maximum length possible; otherwise proceed to the next step.\
\
   2.  If the least significant (left-most) label of N consists of a\
       single octet of the minimum sort value (e.g., 0x00), remove that\
       label; otherwise proceed to the next step.\
\
   3.  If the least significant (right-most) octet in the least\
       significant (left-most) label of N is the minimum sort value,\
       remove the least significant octet and proceed to step 5.\
\
   4.  Decrement the value of the least significant (right-most) octet\
       of the least significant (left-most) label, skipping any values\
       that correspond to uppercase US-ASCII letters, and then append\
\
\
\
Sisson & Laurie               Experimental                      [Page 3]\
\
RFC 4471           DNS Name Predecessor and Successor     September 2006\
\
\
       the least significant (left-most) label with as many octets as\
       possible of the maximum sort value.  Proceed to the next step.\
\
   5.  Prepend N repeatedly with labels of as long a length as possible\
       consisting of octets of the maximum sort value until N is the\
       maximum length possible.\
\
3.1.2.  Derivation of DNS Name Successor\
\
   To derive S(N):\
\
   1.  If N is two or more octets shorter than the maximum DNS name\
       length, prepend N with a label containing a single octet of the\
       minimum sort value (e.g., 0x00); otherwise proceed to the next\
       step.\
\
   2.  If N is one octet shorter than the maximum DNS name length and\
       the least significant (left-most) label is one or more octets\
       shorter than the maximum label length, append an octet of the\
       minimum sort value to the least significant label; otherwise\
       proceed to the next step.\
\
   3.  Increment the value of the least significant (right-most) octet\
       in the least significant (left-most) label that is less than the\
       maximum sort value (e.g., 0xff), skipping any values that\
       correspond to uppercase US-ASCII letters, and then remove any\
       octets to the right of that one.  If all octets in the label are\
       the maximum sort value, then proceed to the next step.\
\
   4.  Remove the least significant (left-most) label.  Unless N is now\
       the same as the owner name of the zone apex (this will occur only\
       if N was the maximum possible name in canonical DNS name order,\
       and thus has wrapped to the owner name of zone apex), repeat\
       starting at step 2.\
\
3.2.  Modified Method\
\
   This method is for use with zones consisting only of single-label\
   owner names where an owner name consisting of label of maximum length\
   would not result in a DNS name that exceeded the maximum DNS name\
   length.  This method is computationally simpler and returns values\
   that are more economical in size than the absolute method.  It\
   differs from the absolute method detailed above in the following\
   ways:\
\
   1.  Step 1 of the derivation P(N) has been omitted as the existence\
       of the owner name of the zone apex never requires denial.\
\
\
\
\
Sisson & Laurie               Experimental                      [Page 4]\
\
RFC 4471           DNS Name Predecessor and Successor     September 2006\
\
\
   2.  A new step 1 has been introduced that removes unnecessary labels.\
\
   3.  Step 4 of the derivation P(N) has been omitted as it is only\
       necessary for zones containing owner names consisting of more\
       than one label.  This omission generally results in a significant\
       reduction of the length of derived predecessors.\
\
   4.  Step 1 of the derivation S(N) had been omitted as it is only\
       necessary for zones containing owner names consisting of more\
       than one label.  This omission results in a tiny reduction of the\
       length of derived successors, and maintains consistency with the\
       modification of step 4 of the derivation P(N) described above.\
\
   5.  Steps 2 and 4 of the derivation S(N) have been modified to\
       eliminate checks for maximum DNS name length, as it is an\
       assumption of this method that no DNS name in the zone can exceed\
       the maximum DNS name length.\
\
3.2.1.  Derivation of DNS Name Predecessor\
\
   To derive P'(N):\
\
   1.  If N is two or more labels longer than the owner name of the\
       apex, repeatedly remove the least significant (left-most) label\
       until N is only one label longer than the owner name of the apex;\
       otherwise proceed to the next step.\
\
   2.  If the least significant (left-most) label of N consists of a\
       single octet of the minimum sort value (e.g., 0x00), remove that\
       label; otherwise proceed to the next step.  (If this condition is\
       met, P'(N) is the owner name of the apex.)\
\
   3.  If the least significant (right-most) octet in the least\
       significant (left-most) label of N is the minimum sort value,\
       remove the least significant octet.\
\
   4.  Decrement the value of the least significant (right-most) octet,\
       skipping any values that correspond to uppercase US-ASCII\
       letters, and then append the label with as many octets as\
       possible of the maximum sort value.\
\
\
\
\
\
\
\
\
\
\
\
Sisson & Laurie               Experimental                      [Page 5]\
\
RFC 4471           DNS Name Predecessor and Successor     September 2006\
\
\
3.2.2.  Derivation of DNS Name Successor\
\
   To derive S'(N):\
\
   1.  If N is two or more labels longer than the owner name of the\
       apex, repeatedly remove the least significant (left-most) label\
       until N is only one label longer than the owner name of the apex.\
       Proceed to the next step.\
\
   2.  If the least significant (left-most) label of N is one or more\
       octets shorter than the maximum label length, append an octet of\
       the minimum sort value to the least significant label; otherwise\
       proceed to the next step.\
\
   3.  Increment the value of the least significant (right-most) octet\
       in the least significant (left-most) label that is less than the\
       maximum sort value (e.g., 0xff), skipping any values that\
       correspond to uppercase US-ASCII letters, and then remove any\
       octets to the right of that one.  If all octets in the label are\
       the maximum sort value, then proceed to the next step.\
\
   4.  Remove the least significant (left-most) label.  (This will occur\
       only if the least significant label is the maximum label length\
       and consists entirely of octets of the maximum sort value, and\
       thus has wrapped to the owner name of the zone apex.)\
\
4.  Notes\
\
4.1.  Test for Existence\
\
   Before using the result of P(N) or P'(N) as the owner name of an NSEC\
   RR in a DNS response, a name server should test to see whether the\
   name exists.  If it does, either a standard non-synthesised NSEC RR\
   should be used, or the synthesised NSEC RR should reflect the RRset\
   types that exist at the NSEC RR's owner name in the Type Bit Map\
   field as specified by Section 4.1.2 of [RFC4034].  Implementors will\
   likely find it simpler to use a non-synthesised NSEC RR.  For further\
   details, see Section 2 of [RFC4470].\
\
\
\
\
\
\
\
\
\
\
\
\
\
Sisson & Laurie               Experimental                      [Page 6]\
\
RFC 4471           DNS Name Predecessor and Successor     September 2006\
\
\
4.2.  Case Considerations\
\
   Section 3.5 of [RFC1034] specifies that "while upper and lower case\
   letters are allowed in names, no significance is attached to the\
   case".  Additionally, Section 6.1 of [RFC4034] states that when\
   determining canonical DNS name order, "uppercase US-ASCII letters are\
   treated as if they were lowercase US-ASCII letters".  Consequently,\
   values corresponding to US-ASCII uppercase letters must be skipped\
   when decrementing and incrementing octets in the derivations\
   described in Section 3.\
\
   The following pseudo-code is illustrative:\
\
   Decrement the value of an octet:\
\
      if (octet == '[')       // '[' is just after uppercase 'Z'\
              octet = '@';    // '@' is just prior to uppercase 'A'\
      else\
              octet--;\
\
   Increment the value of an octet:\
\
      if (octet == '@')       // '@' is just prior to uppercase 'A'\
              octet = '[';    // '[' is just after uppercase 'Z'\
      else\
              octet++;\
\
4.3.  Choice of Range\
\
   [RFC2181] makes the clarification that "any binary string whatever\
   can be used as the label of any resource record".  Consequently, the\
   minimum sort value may be set as 0x00 and the maximum sort value as\
   0xff, and the range of possible values will be any DNS name that\
   contains octets of any value other than those corresponding to\
   uppercase US-ASCII letters.\
\
   However, if all owner names in a zone are in the letter-digit-hyphen,\
   or LDH, format specified in [RFC1034], it may be desirable to\
   restrict the range of possible values to DNS names containing only\
   LDH values.  This has the effect of\
\
   1.  making the output of tools such as `dig' and `nslookup' less\
       subject to confusion,\
\
   2.  minimising the impact that NSEC RRs containing DNS names with\
       non-LDH values (or non-printable values) might have on faulty DNS\
       resolver implementations, and\
\
\
\
\
Sisson & Laurie               Experimental                      [Page 7]\
\
RFC 4471           DNS Name Predecessor and Successor     September 2006\
\
\
   3.  preventing the possibility of results that are wildcard DNS names\
       (see Section 4.4).\
\
   This may be accomplished by using a minimum sort value of 0x1f (US-\
   ASCII character `-') and a maximum sort value of 0x7a (US-ASCII\
   character lowercase `z'), and then skipping non-LDH, non-lowercase\
   values when incrementing or decrementing octets.\
\
4.4.  Wild Card Considerations\
\
   Neither derivation avoids the possibility that the result may be a\
   DNS name containing a wildcard label, i.e., a label containing a\
   single octet with the value 0x2a (US-ASCII character `*').  With\
   additional tests, wildcard DNS names may be explicitly avoided;\
   alternatively, if the range of octet values can be restricted to\
   those corresponding to letter-digit-hyphen, or LDH, characters (see\
   Section 4.3), such DNS names will not occur.\
\
   Note that it is improbable that a result that is a wildcard DNS name\
   will occur unintentionally; even if one does occur either as the\
   owner name of, or in the RDATA of an NSEC RR, it is treated as a\
   literal DNS name with no special meaning.\
\
4.5.  Possible Modifications\
\
4.5.1.  Restriction of Effective Maximum DNS Name Length\
\
   [RFC1034] specifies that "the total number of octets that represent a\
   name (i.e., the sum of all label octets and label lengths) is limited\
   to 255", including the null (zero-length) label that represents the\
   root.  For the purpose of deriving predecessors and successors during\
   NSEC RR synthesis, the maximum DNS name length may be effectively\
   restricted to the length of the longest DNS name in the zone.  This\
   will minimise the size of responses containing synthesised NSEC RRs\
   but, especially in the case of the modified method, may result in\
   some additional computational complexity.\
\
   Note that this modification will have the effect of revealing\
   information about the longest name in the zone.  Moreover, when the\
   contents of the zone changes, e.g., during dynamic updates and zone\
   transfers, care must be taken to ensure that the effective maximum\
   DNS name length agrees with the new contents.\
\
4.5.2.  Use of Modified Method with Zones Containing SRV RRs\
\
   Normally, the modified method cannot be used in zones that contain\
   Service Record (SRV) RRs [RFC2782], as SRV RRs have owner names that\
   contain multiple labels.  However, the use of SRV RRs can be\
\
\
\
Sisson & Laurie               Experimental                      [Page 8]\
\
RFC 4471           DNS Name Predecessor and Successor     September 2006\
\
\
   accommodated by various techniques.  There are at least four possible\
   ways to do this:\
\
   1.  Use conventional NSEC RRs for the region of the zone that\
       contains first-level labels beginning with the underscore (`_')\
       character.  For the purposes of generating these NSEC RRs, the\
       existence of (possibly fictional) ownernames `9{63}' and `a'\
       could be assumed, providing a lower and upper bound for this\
       region.  Then all queries where the QNAME does not exist but\
       contains a first-level label beginning with an underscore could\
       be handled using the normal DNSSEC protocol.\
\
       This approach would make it possible to enumerate all DNS names\
       in the zone containing a first-level label beginning with\
       underscore, including all SRV RRs, but this may be of less a\
       concern to the zone administrator than incurring the overhead of\
       the absolute method or of the following variants of the modified\
       method.\
\
   2.  The absolute method could be used for synthesising NSEC RRs for\
       all queries where the QNAME contains a leading underscore.\
       However, this re-introduces the susceptibility of the absolute\
       method to denial of service activity, as an attacker could send\
       queries for an effectively inexhaustible supply of domain names\
       beginning with a leading underscore.\
\
   3.  A variant of the modified method could be used for synthesising\
       NSEC RRs for all queries where the QNAME contains a leading\
       underscore.  This variant would assume that all predecessors and\
       successors to queries where the QNAME contains a leading\
       underscore may consist of two labels rather than only one.  This\
       introduces a little additional complexity without incurring the\
       full increase in response size and computational complexity as\
       the absolute method.\
\
   4.  Finally, a variant of the modified method that assumes that all\
       owner names in the zone consist of one or two labels could be\
       used.  However, this negates much of the reduction in response\
       size of the modified method and may be nearly as computationally\
       complex as the absolute method.\
\
5.  Examples\
\
   In the following examples,\
\
      the owner name of the zone apex is "example.com.",\
\
\
\
\
\
Sisson & Laurie               Experimental                      [Page 9]\
\
RFC 4471           DNS Name Predecessor and Successor     September 2006\
\
\
      the range of octet values is 0x00 - 0xff excluding values\
      corresponding to uppercase US-ASCII letters, and\
\
      non-printable octet values are expressed as three-digit decimal\
      numbers preceded by a backslash (as specified in Section 5.1 of\
      [RFC1035]).\
\
5.1.  Examples of Immediate Predecessors Using Absolute Method\
\
   Example of a typical case:\
\
      P(foo.example.com.) =\
\
           \\255\\255\\255\\255\\255\\255\\255\\255\\255\\255\\255\\255\
           \\255\\255\\255\\255\\255\\255\\255\\255\\255\\255\\255\\255\
           \\255\\255\\255\\255\\255\\255\\255\\255\\255\\255\\255\\255\
           \\255\\255\\255\\255\\255\\255\\255\\255\\255\\255\\255\\255\
           \\255.\\255\\255\\255\\255\\255\\255\\255\\255\\255\\255\
           \\255\\255\\255\\255\\255\\255\\255\\255\\255\\255\\255\\255\
           \\255\\255\\255\\255\\255\\255\\255\\255\\255\\255\\255\\255\
           \\255\\255\\255\\255\\255\\255\\255\\255\\255\\255\\255\\255\
           \\255\\255\\255\\255\\255\\255\\255\\255\\255\\255\\255\\255\
           \\255\\255\\255\\255\\255.\\255\\255\\255\\255\\255\\255\
           \\255\\255\\255\\255\\255\\255\\255\\255\\255\\255\\255\\255\
           \\255\\255\\255\\255\\255\\255\\255\\255\\255\\255\\255\\255\
           \\255\\255\\255\\255\\255\\255\\255\\255\\255\\255\\255\\255\
           \\255\\255\\255\\255\\255\\255\\255\\255\\255\\255\\255\\255\
           \\255\\255\\255\\255\\255\\255\\255\\255\\255.fon\\255\\255\
           \\255\\255\\255\\255\\255\\255\\255\\255\\255\\255\\255\\255\
           \\255\\255\\255\\255\\255\\255\\255\\255\\255\\255\\255\\255\
           \\255\\255\\255\\255\\255\\255\\255\\255\\255\\255\\255\\255\
           \\255\\255\\255\\255\\255\\255\\255\\255\\255\\255\\255\\255\
           \\255\\255\\255\\255\\255\\255\\255\\255\\255\\255.example.com.\
\
      or, in alternate notation:\
\
           \\255{49}.\\255{63}.\\255{63}.fon\\255{60}.example.com.\
\
      where {n} represents the number of repetitions of an octet.\
\
   Example where least significant (left-most) label of DNS name\
   consists of a single octet of the minimum sort value:\
\
      P(\\000.foo.example.com.) = foo.example.com.\
\
\
\
\
\
\
\
Sisson & Laurie               Experimental                     [Page 10]\
\
RFC 4471           DNS Name Predecessor and Successor     September 2006\
\
\
   Example where least significant (right-most) octet of least\
   significant (left-most) label has the minimum sort value:\
\
      P(foo\\000.example.com.) =\
\
           \\255\\255\\255\\255\\255\\255\\255\\255\\255\\255\\255\\255\
           \\255\\255\\255\\255\\255\\255\\255\\255\\255\\255\\255\\255\
           \\255\\255\\255\\255\\255\\255\\255\\255\\255\\255\\255\\255\
           \\255\\255\\255\\255\\255\\255\\255\\255\\255.\\255\\255\
           \\255\\255\\255\\255\\255\\255\\255\\255\\255\\255\\255\\255\
           \\255\\255\\255\\255\\255\\255\\255\\255\\255\\255\\255\\255\
           \\255\\255\\255\\255\\255\\255\\255\\255\\255\\255\\255\\255\
           \\255\\255\\255\\255\\255\\255\\255\\255\\255\\255\\255\\255\
           \\255\\255\\255\\255\\255\\255\\255\\255\\255\\255\\255\\255\
           \\255.\\255\\255\\255\\255\\255\\255\\255\\255\\255\\255\
           \\255\\255\\255\\255\\255\\255\\255\\255\\255\\255\\255\\255\
           \\255\\255\\255\\255\\255\\255\\255\\255\\255\\255\\255\\255\
           \\255\\255\\255\\255\\255\\255\\255\\255\\255\\255\\255\\255\
           \\255\\255\\255\\255\\255\\255\\255\\255\\255\\255\\255\\255\
           \\255\\255\\255\\255\\255.\\255\\255\\255\\255\\255\\255\
           \\255\\255\\255\\255\\255\\255\\255\\255\\255\\255\\255\\255\
           \\255\\255\\255\\255\\255\\255\\255\\255\\255\\255\\255\\255\
           \\255\\255\\255\\255\\255\\255\\255\\255\\255\\255\\255\\255\
           \\255\\255\\255\\255\\255\\255\\255\\255\\255\\255\\255\\255\
           \\255\\255\\255\\255\\255\\255\\255\\255\\255.foo.example.com.\
\
      or, in alternate notation:\
\
           \\255{45}.\\255{63}.\\255{63}.\\255{63}.foo.example.com.\
\
\
\
\
\
\
\
\
\
\
\
\
\
\
\
\
\
\
\
\
\
\
Sisson & Laurie               Experimental                     [Page 11]\
\
RFC 4471           DNS Name Predecessor and Successor     September 2006\
\
\
   Example where DNS name contains an octet that must be decremented by\
   skipping values corresponding to US-ASCII uppercase letters:\
\
      P(fo\\[.example.com.) =\
\
           \\255\\255\\255\\255\\255\\255\\255\\255\\255\\255\\255\\255\
           \\255\\255\\255\\255\\255\\255\\255\\255\\255\\255\\255\\255\
           \\255\\255\\255\\255\\255\\255\\255\\255\\255\\255\\255\\255\
           \\255\\255\\255\\255\\255\\255\\255\\255\\255\\255\\255\\255\
           \\255.\\255\\255\\255\\255\\255\\255\\255\\255\\255\\255\
           \\255\\255\\255\\255\\255\\255\\255\\255\\255\\255\\255\\255\
           \\255\\255\\255\\255\\255\\255\\255\\255\\255\\255\\255\\255\
           \\255\\255\\255\\255\\255\\255\\255\\255\\255\\255\\255\\255\
           \\255\\255\\255\\255\\255\\255\\255\\255\\255\\255\\255\\255\
           \\255\\255\\255\\255\\255.\\255\\255\\255\\255\\255\\255\
           \\255\\255\\255\\255\\255\\255\\255\\255\\255\\255\\255\\255\
           \\255\\255\\255\\255\\255\\255\\255\\255\\255\\255\\255\\255\
           \\255\\255\\255\\255\\255\\255\\255\\255\\255\\255\\255\\255\
           \\255\\255\\255\\255\\255\\255\\255\\255\\255\\255\\255\\255\
           \\255\\255\\255\\255\\255\\255\\255\\255\\255.fo\\@\\255\
           \\255\\255\\255\\255\\255\\255\\255\\255\\255\\255\\255\\255\
           \\255\\255\\255\\255\\255\\255\\255\\255\\255\\255\\255\\255\
           \\255\\255\\255\\255\\255\\255\\255\\255\\255\\255\\255\\255\
           \\255\\255\\255\\255\\255\\255\\255\\255\\255\\255\\255\\255\
           \\255\\255\\255\\255\\255\\255\\255\\255\\255\\255\\255.example.com.\
\
      or, in alternate notation:\
\
           \\255{49}.\\255{63}.\\255{63}.fo\\@\\255{60}.example.com.\
\
      where {n} represents the number of repetitions of an octet.\
\
\
\
\
\
\
\
\
\
\
\
\
\
\
\
\
\
\
\
\
Sisson & Laurie               Experimental                     [Page 12]\
\
RFC 4471           DNS Name Predecessor and Successor     September 2006\
\
\
   Example where DNS name is the owner name of the zone apex, and\
   consequently wraps to the DNS name with the maximum possible sort\
   order in the zone:\
\
      P(example.com.) =\
\
           \\255\\255\\255\\255\\255\\255\\255\\255\\255\\255\\255\\255\
           \\255\\255\\255\\255\\255\\255\\255\\255\\255\\255\\255\\255\
           \\255\\255\\255\\255\\255\\255\\255\\255\\255\\255\\255\\255\
           \\255\\255\\255\\255\\255\\255\\255\\255\\255\\255\\255\\255\
           \\255.\\255\\255\\255\\255\\255\\255\\255\\255\\255\\255\
           \\255\\255\\255\\255\\255\\255\\255\\255\\255\\255\\255\\255\
           \\255\\255\\255\\255\\255\\255\\255\\255\\255\\255\\255\\255\
           \\255\\255\\255\\255\\255\\255\\255\\255\\255\\255\\255\\255\
           \\255\\255\\255\\255\\255\\255\\255\\255\\255\\255\\255\\255\
           \\255\\255\\255\\255\\255.\\255\\255\\255\\255\\255\\255\
           \\255\\255\\255\\255\\255\\255\\255\\255\\255\\255\\255\\255\
           \\255\\255\\255\\255\\255\\255\\255\\255\\255\\255\\255\\255\
           \\255\\255\\255\\255\\255\\255\\255\\255\\255\\255\\255\\255\
           \\255\\255\\255\\255\\255\\255\\255\\255\\255\\255\\255\\255\
           \\255\\255\\255\\255\\255\\255\\255\\255\\255.\\255\\255\
           \\255\\255\\255\\255\\255\\255\\255\\255\\255\\255\\255\\255\
           \\255\\255\\255\\255\\255\\255\\255\\255\\255\\255\\255\\255\
           \\255\\255\\255\\255\\255\\255\\255\\255\\255\\255\\255\\255\
           \\255\\255\\255\\255\\255\\255\\255\\255\\255\\255\\255\\255\
           \\255\\255\\255\\255\\255\\255\\255\\255\\255\\255\\255\\255\
           \\255.example.com.\
\
      or, in alternate notation:\
\
           \\255{49}.\\255{63}.\\255{63}.\\255{63}.example.com.\
\
\
\
\
\
\
\
\
\
\
\
\
\
\
\
\
\
\
\
\
Sisson & Laurie               Experimental                     [Page 13]\
\
RFC 4471           DNS Name Predecessor and Successor     September 2006\
\
\
5.2.  Examples of Immediate Successors Using Absolute Method\
\
   Example of typical case:\
\
      S(foo.example.com.) = \\000.foo.example.com.\
\
   Example where DNS name is one octet short of the maximum DNS name\
   length:\
\
      N =  fooooooooooooooooooooooooooooooooooooooooooooooo\
           .ooooooooooooooooooooooooooooooooooooooooooooooo\
           oooooooooooooooo.ooooooooooooooooooooooooooooooo\
           oooooooooooooooooooooooooooooooo.ooooooooooooooo\
           oooooooooooooooooooooooooooooooooooooooooooooooo.example.com.\
\
      or, in alternate notation:\
\
           fo{47}.o{63}.o{63}.o{63}.example.com.\
\
      S(N) =\
\
           fooooooooooooooooooooooooooooooooooooooooooooooo\
           \\000.ooooooooooooooooooooooooooooooooooooooooooo\
           oooooooooooooooooooo.ooooooooooooooooooooooooooo\
           oooooooooooooooooooooooooooooooooooo.ooooooooooo\
           oooooooooooooooooooooooooooooooooooooooooooooooo\
           oooo.example.com.\
\
      or, in alternate notation:\
\
           fo{47}\\000.o{63}.o{63}.o{63}.example.com.\
\
\
\
\
\
\
\
\
\
\
\
\
\
\
\
\
\
\
\
\
Sisson & Laurie               Experimental                     [Page 14]\
\
RFC 4471           DNS Name Predecessor and Successor     September 2006\
\
\
   Example where DNS name is the maximum DNS name length:\
\
      N  = fooooooooooooooooooooooooooooooooooooooooooooooo\
           o.oooooooooooooooooooooooooooooooooooooooooooooo\
           ooooooooooooooooo.oooooooooooooooooooooooooooooo\
           ooooooooooooooooooooooooooooooooo.oooooooooooooo\
           oooooooooooooooooooooooooooooooooooooooooooooooo\
           o.example.com.\
\
      or, in alternate notation:\
\
           fo{48}.o{63}.o{63}.o{63}.example.com.\
\
      S(N) =\
\
           fooooooooooooooooooooooooooooooooooooooooooooooo\
           p.oooooooooooooooooooooooooooooooooooooooooooooo\
           ooooooooooooooooo.oooooooooooooooooooooooooooooo\
           ooooooooooooooooooooooooooooooooo.oooooooooooooo\
           oooooooooooooooooooooooooooooooooooooooooooooooo\
           o.example.com.\
\
      or, in alternate notation:\
\
           fo{47}p.o{63}.o{63}.o{63}.example.com.\
\
\
\
\
\
\
\
\
\
\
\
\
\
\
\
\
\
\
\
\
\
\
\
\
\
\
Sisson & Laurie               Experimental                     [Page 15]\
\
RFC 4471           DNS Name Predecessor and Successor     September 2006\
\
\
   Example where DNS name is the maximum DNS name length and the least\
   significant (left-most) label has the maximum sort value:\
\
      N =  \\255\\255\\255\\255\\255\\255\\255\\255\\255\\255\\255\\255\
           \\255\\255\\255\\255\\255\\255\\255\\255\\255\\255\\255\\255\
           \\255\\255\\255\\255\\255\\255\\255\\255\\255\\255\\255\\255\
           \\255\\255\\255\\255\\255\\255\\255\\255\\255\\255\\255\\255\
           \\255.ooooooooooooooooooooooooooooooooooooooooooo\
           oooooooooooooooooooo.ooooooooooooooooooooooooooo\
           oooooooooooooooooooooooooooooooooooo.ooooooooooo\
           oooooooooooooooooooooooooooooooooooooooooooooooo\
           oooo.example.com.\
\
      or, in alternate notation:\
\
           \\255{49}.o{63}.o{63}.o{63}.example.com.\
\
      S(N) =\
\
           oooooooooooooooooooooooooooooooooooooooooooooooo\
           oooooooooooooop.oooooooooooooooooooooooooooooooo\
           ooooooooooooooooooooooooooooooo.oooooooooooooooo\
           ooooooooooooooooooooooooooooooooooooooooooooooo.\
           example.com.\
\
      or, in alternate notation:\
\
           o{62}p.o{63}.o{63}.example.com.\
\
\
\
\
\
\
\
\
\
\
\
\
\
\
\
\
\
\
\
\
\
\
\
Sisson & Laurie               Experimental                     [Page 16]\
\
RFC 4471           DNS Name Predecessor and Successor     September 2006\
\
\
   Example where DNS name is the maximum DNS name length and the eight\
   least significant (right-most) octets of the least significant\
   (left-most) label have the maximum sort value:\
\
      N  = foooooooooooooooooooooooooooooooooooooooo\\255\
           \\255\\255\\255\\255\\255\\255\\255.ooooooooooooooooooo\
           oooooooooooooooooooooooooooooooooooooooooooo.ooo\
           oooooooooooooooooooooooooooooooooooooooooooooooo\
           oooooooooooo.ooooooooooooooooooooooooooooooooooo\
           oooooooooooooooooooooooooooo.example.com.\
\
      or, in alternate notation:\
\
           fo{40}\\255{8}.o{63}.o{63}.o{63}.example.com.\
\
      S(N) =\
\
           fooooooooooooooooooooooooooooooooooooooop.oooooo\
           oooooooooooooooooooooooooooooooooooooooooooooooo\
           ooooooooo.oooooooooooooooooooooooooooooooooooooo\
           ooooooooooooooooooooooooo.oooooooooooooooooooooo\
           ooooooooooooooooooooooooooooooooooooooooo.example.com.\
\
      or, in alternate notation:\
\
           fo{39}p.o{63}.o{63}.o{63}.example.com.\
\
\
\
\
\
\
\
\
\
\
\
\
\
\
\
\
\
\
\
\
\
\
\
\
\
Sisson & Laurie               Experimental                     [Page 17]\
\
RFC 4471           DNS Name Predecessor and Successor     September 2006\
\
\
   Example where DNS name is the maximum DNS name length and contains an\
   octet that must be incremented by skipping values corresponding to\
   US-ASCII uppercase letters:\
\
      N  = fooooooooooooooooooooooooooooooooooooooooooooooo\
           \\@.ooooooooooooooooooooooooooooooooooooooooooooo\
           oooooooooooooooooo.ooooooooooooooooooooooooooooo\
           oooooooooooooooooooooooooooooooooo.ooooooooooooo\
           oooooooooooooooooooooooooooooooooooooooooooooooo\
           oo.example.com.\
\
      or, in alternate notation:\
\
           fo{47}\\@.o{63}.o{63}.o{63}.example.com.\
\
      S(N) =\
\
           fooooooooooooooooooooooooooooooooooooooooooooooo\
           \\[.ooooooooooooooooooooooooooooooooooooooooooooo\
           oooooooooooooooooo.ooooooooooooooooooooooooooooo\
           oooooooooooooooooooooooooooooooooo.ooooooooooooo\
           oooooooooooooooooooooooooooooooooooooooooooooooo\
           oo.example.com.\
\
      or, in alternate notation:\
\
           fo{47}\\[.o{63}.o{63}.o{63}.example.com.\
\
\
\
\
\
\
\
\
\
\
\
\
\
\
\
\
\
\
\
\
\
\
\
\
Sisson & Laurie               Experimental                     [Page 18]\
\
RFC 4471           DNS Name Predecessor and Successor     September 2006\
\
\
   Example where DNS name has the maximum possible sort order in the\
   zone, and consequently wraps to the owner name of the zone apex:\
\
      N  = \\255\\255\\255\\255\\255\\255\\255\\255\\255\\255\\255\\255\
           \\255\\255\\255\\255\\255\\255\\255\\255\\255\\255\\255\\255\
           \\255\\255\\255\\255\\255\\255\\255\\255\\255\\255\\255\\255\
           \\255\\255\\255\\255\\255\\255\\255\\255\\255\\255\\255\\255\
           \\255.\\255\\255\\255\\255\\255\\255\\255\\255\\255\\255\
           \\255\\255\\255\\255\\255\\255\\255\\255\\255\\255\\255\\255\
           \\255\\255\\255\\255\\255\\255\\255\\255\\255\\255\\255\\255\
           \\255\\255\\255\\255\\255\\255\\255\\255\\255\\255\\255\\255\
           \\255\\255\\255\\255\\255\\255\\255\\255\\255\\255\\255\\255\
           \\255\\255\\255\\255\\255.\\255\\255\\255\\255\\255\\255\
           \\255\\255\\255\\255\\255\\255\\255\\255\\255\\255\\255\\255\
           \\255\\255\\255\\255\\255\\255\\255\\255\\255\\255\\255\\255\
           \\255\\255\\255\\255\\255\\255\\255\\255\\255\\255\\255\\255\
           \\255\\255\\255\\255\\255\\255\\255\\255\\255\\255\\255\\255\
           \\255\\255\\255\\255\\255\\255\\255\\255\\255.\\255\\255\
           \\255\\255\\255\\255\\255\\255\\255\\255\\255\\255\\255\\255\
           \\255\\255\\255\\255\\255\\255\\255\\255\\255\\255\\255\\255\
           \\255\\255\\255\\255\\255\\255\\255\\255\\255\\255\\255\\255\
           \\255\\255\\255\\255\\255\\255\\255\\255\\255\\255\\255\\255\
           \\255\\255\\255\\255\\255\\255\\255\\255\\255\\255\\255\\255\
           \\255.example.com.\
\
      or, in alternate notation:\
\
           \\255{49}.\\255{63}.\\255{63}.\\255{63}.example.com.\
\
      S(N) = example.com.\
\
5.3.  Examples of Predecessors Using Modified Method\
\
   Example of a typical case:\
\
      P'(foo.example.com.) =\
\
           fon\\255\\255\\255\\255\\255\\255\\255\\255\\255\\255\\255\
           \\255\\255\\255\\255\\255\\255\\255\\255\\255\\255\\255\\255\
           \\255\\255\\255\\255\\255\\255\\255\\255\\255\\255\\255\\255\
           \\255\\255\\255\\255\\255\\255\\255\\255\\255\\255\\255\\255\
           \\255\\255\\255\\255\\255\\255\\255\\255\\255\\255\\255\\255\
           \\255.example.com.\
\
      or, in alternate notation:\
\
           fon\\255{60}.example.com.\
\
\
\
\
Sisson & Laurie               Experimental                     [Page 19]\
\
RFC 4471           DNS Name Predecessor and Successor     September 2006\
\
\
   Example where DNS name contains more labels than DNS names in the\
   zone:\
\
      P'(bar.foo.example.com.) = foo.example.com.\
\
   Example where least significant (right-most) octet of least\
   significant (left-most) label has the minimum sort value:\
\
      P'(foo\\000.example.com.) = foo.example.com.\
\
   Example where least significant (left-most) label has the minimum\
   sort value:\
\
      P'(\\000.example.com.) = example.com.\
\
   Example where DNS name is the owner name of the zone apex, and\
   consequently wraps to the DNS name with the maximum possible sort\
   order in the zone:\
\
      P'(example.com.) =\
\
           \\255\\255\\255\\255\\255\\255\\255\\255\\255\\255\\255\\255\
           \\255\\255\\255\\255\\255\\255\\255\\255\\255\\255\\255\\255\
           \\255\\255\\255\\255\\255\\255\\255\\255\\255\\255\\255\\255\
           \\255\\255\\255\\255\\255\\255\\255\\255\\255\\255\\255\\255\
           \\255\\255\\255\\255\\255\\255\\255\\255\\255\\255\\255\\255\
           \\255\\255\\255.example.com.\
\
      or, in alternate notation:\
\
           \\255{63}.example.com.\
\
5.4.  Examples of Successors Using Modified Method\
\
   Example of a typical case:\
\
      S'(foo.example.com.) = foo\\000.example.com.\
\
   Example where DNS name contains more labels than DNS names in the\
   zone:\
\
      S'(bar.foo.example.com.) = foo\\000.example.com.\
\
\
   Example where least significant (left-most) label has the maximum\
   sort value, and consequently wraps to the owner name of the zone\
   apex:\
\
\
\
\
Sisson & Laurie               Experimental                     [Page 20]\
\
RFC 4471           DNS Name Predecessor and Successor     September 2006\
\
\
      N  = \\255\\255\\255\\255\\255\\255\\255\\255\\255\\255\\255\\255\
           \\255\\255\\255\\255\\255\\255\\255\\255\\255\\255\\255\\255\
           \\255\\255\\255\\255\\255\\255\\255\\255\\255\\255\\255\\255\
           \\255\\255\\255\\255\\255\\255\\255\\255\\255\\255\\255\\255\
           \\255\\255\\255\\255\\255\\255\\255\\255\\255\\255\\255\\255\
           \\255\\255\\255.example.com.\
\
      or, in alternate notation:\
\
           \\255{63}.example.com.\
\
      S'(N) = example.com.\
\
6.  Security Considerations\
\
   The derivation of some predecessors/successors requires the testing\
   of more conditions than others.  Consequently, the effectiveness of a\
   denial-of-service attack may be enhanced by sending queries that\
   require more conditions to be tested.  The modified method involves\
   the testing of fewer conditions than the absolute method and\
   consequently is somewhat less susceptible to this exposure.\
\
7.  Acknowledgements\
\
   The authors would like to thank Sam Weiler, Olaf Kolkman, Olafur\
   Gudmundsson, and Niall O'Reilly for their review and input.\
\
8.  References\
\
8.1.  Normative References\
\
   [RFC1034]      Mockapetris, P., "Domain names - concepts and\
                  facilities", STD 13, RFC 1034, November 1987.\
\
   [RFC1035]      Mockapetris, P., "Domain names - implementation and\
                  specification", STD 13, RFC 1035, November 1987.\
\
   [RFC2181]      Elz, R. and R. Bush, "Clarifications to the DNS\
                  Specification", RFC 2181, July 1997.\
\
   [RFC2782]      Gulbrandsen, A., Vixie, P., and L. Esibov, "A DNS RR\
                  for specifying the location of services (DNS SRV)",\
                  RFC 2782, February 2000.\
\
   [RFC4034]      Arends, R., Austein, R., Larson, M., Massey, D., and\
                  S. Rose, "Resource Records for the DNS Security\
                  Extensions", RFC 4034, March 2005.\
\
\
\
\
Sisson & Laurie               Experimental                     [Page 21]\
\
RFC 4471           DNS Name Predecessor and Successor     September 2006\
\
\
8.2.  Informative References\
\
   [RFC4470]      Weiler, S. and J. Ihren, "Minimally Covering NSEC\
                  Records and DNSSEC On-line Signing", RFC 4470, April\
                  2006.\
\
   [DNSSEC-TRANS] Arends, R., Koch, P., and J. Schlyter, "Evaluating\
                  DNSSEC Transition Mechanisms", Work in Progress,\
                  February 2005.\
\
Authors' Addresses\
\
   Geoffrey Sisson\
   Nominet\
   Sandford Gate\
   Sandy Lane West\
   Oxford\
   OX4 6LB\
   GB\
\
   Phone: +44 1865 332211\
   EMail: geoff@nominet.org.uk\
\
\
   Ben Laurie\
   Nominet\
   17 Perryn Road\
   London\
   W3 7LR\
   GB\
\
   Phone: +44 20 8735 0686\
   EMail: ben@algroup.co.uk\
\
\
\
\
\
\
\
\
\
\
\
\
\
\
\
\
\
\
Sisson & Laurie               Experimental                     [Page 22]\
\
RFC 4471           DNS Name Predecessor and Successor     September 2006\
\
\
Full Copyright Statement\
\
   Copyright (C) The Internet Society (2006).\
\
   This document is subject to the rights, licenses and restrictions\
   contained in BCP 78, and except as set forth therein, the authors\
   retain all their rights.\
\
   This document and the information contained herein are provided on an\
   "AS IS" basis and THE CONTRIBUTOR, THE ORGANIZATION HE/SHE REPRESENTS\
   OR IS SPONSORED BY (IF ANY), THE INTERNET SOCIETY AND THE INTERNET\
   ENGINEERING TASK FORCE DISCLAIM ALL WARRANTIES, EXPRESS OR IMPLIED,\
   INCLUDING BUT NOT LIMITED TO ANY WARRANTY THAT THE USE OF THE\
   INFORMATION HEREIN WILL NOT INFRINGE ANY RIGHTS OR ANY IMPLIED\
   WARRANTIES OF MERCHANTABILITY OR FITNESS FOR A PARTICULAR PURPOSE.\
\
Intellectual Property\
\
   The IETF takes no position regarding the validity or scope of any\
   Intellectual Property Rights or other rights that might be claimed to\
   pertain to the implementation or use of the technology described in\
   this document or the extent to which any license under such rights\
   might or might not be available; nor does it represent that it has\
   made any independent effort to identify any such rights.  Information\
   on the procedures with respect to rights in RFC documents can be\
   found in BCP 78 and BCP 79.\
\
   Copies of IPR disclosures made to the IETF Secretariat and any\
   assurances of licenses to be made available, or the result of an\
   attempt made to obtain a general license or permission for the use of\
   such proprietary rights by implementers or users of this\
   specification can be obtained from the IETF on-line IPR repository at\
   http://www.ietf.org/ipr.\
\
   The IETF invites any interested party to bring to its attention any\
   copyrights, patents or patent applications, or other proprietary\
   rights that may cover technology that may be required to implement\
   this standard.  Please address the information to the IETF at\
   ietf-ipr@ietf.org.\
\
Acknowledgement\
\
   Funding for the RFC Editor function is provided by the IETF\
   Administrative Support Activity (IASA).\
\
\
\
\
\
\
\
Sisson & Laurie               Experimental                     [Page 23]\
\

doc 15
  field 0
    name titolo
    type string
    value rfc4477.txt
  field 1
    name contenuto
    type string
    value \
\
\
\
\
\
Network Working Group                                           T. Chown\
Request for Comments: 4477                     University of Southampton\
Category: Informational                                        S. Venaas\
                                                                 UNINETT\
                                                               C. Strauf\
                                      Clausthal University of Technology\
                                                                May 2006\
\
\
              Dynamic Host Configuration Protocol (DHCP):\
                    IPv4 and IPv6 Dual-Stack Issues\
\
Status of This Memo\
\
   This memo provides information for the Internet community.  It does\
   not specify an Internet standard of any kind.  Distribution of this\
   memo is unlimited.\
\
Copyright Notice\
\
   Copyright (C) The Internet Society (2006).\
\
Abstract\
\
   A node may have support for communications using IPv4 and/or IPv6\
   protocols.  Such a node may wish to obtain IPv4 and/or IPv6\
   configuration settings via the Dynamic Host Configuration Protocol\
   (DHCP).  The original version of DHCP (RFC 2131) designed for IPv4\
   has now been complemented by a new DHCPv6 (RFC 3315) for IPv6.  This\
   document describes issues identified with dual IP version DHCP\
   interactions, the most important aspect of which is how to handle\
   potential problems in clients processing configuration information\
   received from both DHCPv4 and DHCPv6 servers.  The document makes a\
   recommendation on the general strategy on how best to handle such\
   issues and identifies future work to be undertaken.\
\
\
\
\
\
\
\
\
\
\
\
\
\
\
\
\
Chown, et al.                Informational                      [Page 1]\
\
RFC 4477                DHCP: Dual-Stack Issues                 May 2006\
\
\
Table of Contents\
\
   1. Introduction ....................................................3\
   2. Configuration Scenarios .........................................3\
   3. Dual-Stack Issues ...............................................4\
      3.1. Handling Multiple Responses ................................4\
      3.2. Different Administrative Management ........................5\
      3.3. Multiple Interfaces ........................................5\
      3.4. DNS Load Balancing .........................................5\
      3.5. DNS Search Path Issues .....................................5\
      3.6. Protocol Startup Sequence ..................................6\
      3.7. DHCP Option Variations .....................................6\
      3.8. Security Issues ............................................6\
   4. Potential Solutions .............................................7\
      4.1. Separate DHCP Servers ......................................7\
      4.2. Single DHCPv6 Server .......................................8\
      4.3. Optimising for Failure with Lists of Addresses .............9\
      4.4. Administrative and Other Areas ............................10\
   5. Summary ........................................................10\
   6. Security Considerations ........................................12\
   7. Acknowledgements ...............................................12\
   8. Informative References .........................................12\
\
\
\
\
\
\
\
\
\
\
\
\
\
\
\
\
\
\
\
\
\
\
\
\
\
\
\
\
\
Chown, et al.                Informational                      [Page 2]\
\
RFC 4477                DHCP: Dual-Stack Issues                 May 2006\
\
\
1.  Introduction\
\
   The original specification of the Dynamic Host Configuration Protocol\
   (DHCP) was made with only IPv4 in mind.  That specification has been\
   subsequently revised, up to the latest version of DHCP [1].  With the\
   arrival of IPv6, a new DHCP specification for IPv6 has been designed\
   and published as DHCPv6 [4].\
\
   These protocols allow nodes to communicate via IPv4 or IPv6\
   (respectively) to retrieve configuration settings for operation in a\
   managed environment.  While an IPv6 node may acquire address-related\
   configuration settings via IPv6 stateless address autoconfiguration\
   [2], such a node may wish to use stateless DHCPv6 [5] for other\
   administratively configured options, such as DNS or NTP.\
\
   In early IPv6 deployments, a dual-stack mode of operation is\
   typically used.  There will thus be nodes that require both IPv4 and\
   IPv6 configuration settings.  This document discusses issues with\
   obtaining such settings in a dual-stack environment.\
\
   There is a general multihoming issue to be solved for DHCP.  A host\
   might simultaneously be connected to multiple networks managed by\
   multiple parties.  Also, IPv4 and IPv6 might be managed by separate\
   parties.  While these issues are touched on in this document, here we\
   focus on the specific issues for operating DHCP in a mixed (typically\
   dual-stack) IPv4 and IPv6 environment within a single administrative\
   domain.\
\
   In this document, we refer to a "DHCP server" as a server\
   implementing the original DHCP [1], and a "DHCPv6 server" as a server\
   implementing DHCPv6 [4] or its stateless subset [5].\
\
2.  Configuration Scenarios\
\
   For a node in an IPv4-only or IPv6-only environment, the choice of\
   DHCP server is a straightforward one; a DHCP server for IPv4, or a\
   DHCPv6 server for IPv6.\
\
   In a dual-stack environment a node in a managed environment will need\
   to obtain both IPv4 and IPv6 configuration settings, such as the\
   following:\
\
   o  IPv4 address\
\
   o  IPv6 address\
\
   o  NTP server\
\
\
\
\
Chown, et al.                Informational                      [Page 3]\
\
RFC 4477                DHCP: Dual-Stack Issues                 May 2006\
\
\
   o  DNS server\
\
   o  NIS server\
\
   o  DNS search path\
\
   While the format of address settings will be IP specific, the node\
   may equally well acquire IPv4 or IPv6 addresses for some settings,\
   such as for DNS or NTP, if those services are available via IPv4 or\
   IPv6 transport.  Currently, a DHCP server returns IPv4 data, while a\
   DHCPv6 server returns IPv6 data.\
\
   It is worth noting that in an IPv4 environment, with a DHCP server,\
   the choice of whether to use DHCP is made by the node.  In an IPv6\
   environment, the use of the managed and other bits in the Router\
   Advertisement can offer a hint to the node whether or not to use full\
   DHCPv6 or its stateless variant.  It is perhaps not clear whether a\
   dual-stack node should do DHCP for IPv4 if Managed and OtherConfig\
   flags in the Router Advertisement are both off; it seems most\
   appropriate that the decision to use DHCP for IPv4 or not should be\
   as if the host were IPv4-only.\
\
3.  Dual-Stack Issues\
\
   In this section, we list issues that have been raised to date,\
   related to dual-stack DHCP operation.\
\
   It has been noted from comments that the first four, and possibly\
   five, subsections here may also be viewed as multihoming issues.\
\
3.1.  Handling Multiple Responses\
\
   The general question is how to handle configuration information that\
   may be gathered from multiple sources.  Where those sources are DHCP\
   and DHCPv6 servers (which may be two physical nodes or two servers\
   running on the same node) the client node needs to know whether to\
   use the most recent data, or whether to perform some merger or union\
   of the responses by certain rules.  A method for merging lists of\
   addresses, for options that carry such information, may also be\
   required.  A node may choose to ask a DHCPv6 server and only use a\
   DHCP server if no response is received.\
\
   Merging is possible, but is likely to be complex.  There could be\
   some priority, so that if both DHCP and DHCPv6 servers offer a value,\
   only one is used.  Or the node could choose to store and use both, in\
   some order of its choosing.  Merging issues are further discussed\
   later in this document.\
\
\
\
\
Chown, et al.                Informational                      [Page 4]\
\
RFC 4477                DHCP: Dual-Stack Issues                 May 2006\
\
\
   A node may also obtain information from other sources, such as a\
   manual configuration file (for example, /etc/resolv.conf for DNS data\
   on many UNIX systems).  A node configured manually to use an IPv6 DNS\
   server may lose that configuration if it is in a dual-stack\
   environment and uses DHCP to obtain IPv4 settings; the new IPv4\
   settings from the DHCP response may then overwrite the manual IPv6\
   DNS setting.\
\
3.2.  Different Administrative Management\
\
   In some deployments, the IPv4 and IPv6 services may not be\
   administered by the same organisation or people, such as in a\
   community wireless environment.  This poses problems for consistency\
   of data offered by either DHCP version.\
\
   There may also be different connectivity for the protocols, and the\
   client may gain advantage from knowing which 'administrative domain'\
   is supplying which information.  A client may need to use different\
   received information depending on which connectivity is being used.\
   In the example of the community wireless environment, the question of\
   which connectivity is 'better' is a separate issue.\
\
3.3.  Multiple Interfaces\
\
   A node may have multiple interfaces and run IPv4 and IPv6 on\
   different interfaces.  A question then is whether the settings are\
   per interface or per node.\
\
   Per-interface settings can be complex because a client node needs to\
   know which interface system settings, like NTP server, came from.\
   And it may not be apparent which setting should be used if, for\
   example, an NTP server option is received on multiple interfaces,\
   potentially over different protocols.\
\
3.4.  DNS Load Balancing\
\
   In some cases it is preferable to list DNS server information in an\
   ordered way per node for load balancing, giving different responses\
   to different clients.  Responses from different DHCP and DHCPv6\
   servers may make such configuration problematic, if the knowledge of\
   the load balancing is not available to both servers.\
\
3.5.  DNS Search Path Issues\
\
   The DNS search path may vary for administrative reasons.  For\
   example, a site under the domain example.com may choose to place an\
   early IPv6 deployment under the subdomain ipv6.example.com, until it\
   is confident of offering a full dual-stack service under its main\
\
\
\
Chown, et al.                Informational                      [Page 5]\
\
RFC 4477                DHCP: Dual-Stack Issues                 May 2006\
\
\
   domain.  The subtlety here is that the DNS search path then affects\
   the choice of protocol used, such as IPv6 for nodes in\
   ipv6.example.com.\
\
3.6.  Protocol Startup Sequence\
\
   In the dual-stack environment, one needs to consider what happens if,\
   for example, the IPv6 interface (transport) is started after DHCPv4\
   was used to configure the client.  Should the client then simply\
   discard the current IPv4 information, or merge it with a subsequent\
   IPv6 response?  It may also be possible that one protocol is shut\
   down or started while the system is running.  There are similarities\
   here to issues when DHCP renewals have information that may appear\
   that previously was not available (or no longer carry information\
   that has been removed).\
\
3.7.  DHCP Option Variations\
\
   Some options in DHCP are not available in DHCPv6 and vice versa.\
   Some IP-version limitations naturally apply; for example, only IPv6\
   addresses can be in an IPv6 NTP option.  The DHCP and DHCPv6 option\
   numbers may be different.\
\
   Some sites may choose to use IPv4-mapped addresses in DHCPv6-based\
   options.  The merits and drawbacks of such an approach need\
   discussion.\
\
   A site administrator may wish to configure all their dual-stack nodes\
   with (say) two NTP servers, one of which has an IPv4 address, the\
   other an IPv6 address.  In this case, it may be desirable for an NTP\
   option to carry a list of addresses, where some may be IPv4 and some\
   may be IPv6.  In general one could consider having DHCPv6 options\
   that can carry a mix of IPv4 and IPv6 addresses.\
\
3.8.  Security Issues\
\
   This document does not introduce any new security issues per se.  A\
   detailed analysis of DHCP and DHCPv6 security is out of scope for\
   this document.\
\
   While there is a specification for authentication for DHCP messages\
   [3], the standard seems to have very few, if any, implementations.\
   Thus DHCP and DHCPv6 servers are still liable to be spoofed.  Adding\
   an additional protocol may give an extra avenue for attack, should an\
   attacker perhaps spoof a DHCPv6 server but not a DHCP server.\
\
\
\
\
\
\
Chown, et al.                Informational                      [Page 6]\
\
RFC 4477                DHCP: Dual-Stack Issues                 May 2006\
\
\
4.  Potential Solutions\
\
   Here we discuss the two broad solution strategies proposed within the\
   IETF dhc WG.  The first is to run separate DHCP and DHCPv6 servers\
   (with the client merging information received from both where\
   necessary, or perhaps choosing to query a particular version first).\
   The second is to run only a DHCPv6 server and relay IPv4\
   configuration information within (new) IPv4 configuration options.\
\
4.1.  Separate DHCP Servers\
\
   One solution is to run separate DHCP and DHCPv6 servers.  These may\
   or may not be run on the same physical node.  The information served\
   from the DHCP servers could be generated from a single database\
   instance for consistency.  One might have a single server instance\
   supporting both DHCPv4 and DHCPv6 protocols.\
\
   In this approach, some best practice guidance is required for how\
   multiple responses are handled or merged.  Administrators have the\
   onus to maintain consistency (for example, scripts may generate\
   common DHCP and DHCPv6 configuration files).\
\
   In some cases, inconsistencies may not matter.  In a simple case, an\
   NTP server will give the same time whether accessed by IPv4 or IPv6.\
   Even if different recursive DNS servers are offered via DHCP or\
   DHCPv6, then those name servers should provide the same response to a\
   given query.  In cases where sites may be operating a 'two-faced\
   DNS', this will still hold true if the node is on the same\
   topological point on the network from an IPv4 or IPv6 perspective.\
   The order of DNS servers in a node's configuration is not important,\
   unless DNS load balancing is required.\
\
   In other cases, inconsistencies may be an issue; for example, where\
   lists of values are returned, an algorithm is needed for list merger\
   (e.g., "alternate, DHCPv6 first").  Or there may be incompatible\
   configuration values where, for example, DHCPv6 supplies domain names\
   (such the SMTP or POP servers) whereas DHCPv4 provides only IPv4\
   addresses.\
\
   In the case of separate servers, there are some options, like DNS\
   search path, that aren't used in a specific IP protocol context.\
\
   The multiple server approach will have some simplifications.  The\
   DHCPv4 and DHCPv6 servers may provide the same value for a particular\
   parameter, in which case there is no conflict.  In some cases, the\
   value may be different, but the effect should be the same (such as an\
\
\
\
\
\
Chown, et al.                Informational                      [Page 7]\
\
RFC 4477                DHCP: Dual-Stack Issues                 May 2006\
\
\
   NTP server).  The crux of the issue is to identify where differences\
   may occur and where these differences will have an impact on node\
   behaviour.\
\
   One possible solution is to have per-host preferences, or an ordered\
   list of preferences, for example, "use manually configured", "prefer\
   DHCPv4", or "prefer DHCPv6", assuming the host can act based upon\
   which protocol is used.  It is then up to the site administrator to\
   ensure that values returned from either DHCP are consistent (a\
   principle that extends if other methods are used, such as NIS or\
   Service Location Protocol (SLP)).\
\
4.2.  Single DHCPv6 Server\
\
   There is an argument for not having to configure and operate both\
   DHCP and DHCPv6 servers in a dual-stack site environment.  The use of\
   both servers may also lead to some redundancy in the information\
   served.  Thus, one solution may be to modify DHCPv6 to be able to\
   return IPv4 information.  This solution is hinted at in the DHCPv6\
   [4] specification: "If there is sufficient interest and demand,\
   integration can be specified in a document that extends DHCPv6 to\
   carry IPv4 addresses and configuration information."  This solution\
   may allow DHCP for IPv4 to be completely replaced by DHCPv6 with\
   additional IPv4 information options, for dual-stack nodes.\
\
   A general argument is that which DHCP protocol is used (whether it's\
   over IPv4 or IPv6) shouldn't affect what kind of addresses you can\
   get configured with it, and that simplicity and predictability come\
   from using a single server over a single transport.  IPv4-capable\
   hosts will likely remain for at least 10 years, probably much longer;\
   do we want dual-stack hosts (which will become the norm) to do both\
   DHCPv4 and DHCPv6 forever while dual-stack?  If you need both servers\
   to configure interfaces with addresses, and get other configurations,\
   then you rely on two separate protocols to work (servers and relays,\
   etc.) in order for the host to behave correctly.\
\
   This approach may require the listing of a mix of IPv4 and IPv6\
   addresses for an option.  This could then be considered when new IPv6\
   options are introduced.  There could be just two options needed, one\
   new option for the address delegation, and one for doing\
   encapsulation.\
\
   Also, there are a number of paradigms in DHCPv6 that we miss in\
   DHCPv4.  An example is movement away from using MAC addresses for\
   per-host address assignment and instead using DHCP Unique Identifier\
   (DUIDs) or Identity Association Identifiers (IAIDs).  As stated in\
   Section 9 of RFC3315, DHCPv6 servers use DUIDs to identify clients\
   for the selection of configuration parameters and in the association\
\
\
\
Chown, et al.                Informational                      [Page 8]\
\
RFC 4477                DHCP: Dual-Stack Issues                 May 2006\
\
\
   of IAs with clients.  DHCPv6 clients use DUIDs to identify a server\
   in messages where a server needs to be identified.  However, in this\
   particular example, the new DHCPv6 functionality has recently been\
   retrofitted to IPv4 via a specification for DUIDs for DHCPv4 [6].\
\
   However, there are a number of potential problems with this approach:\
\
   o  IPv4-only nodes would not have any DHCP service available to them;\
      such an approach is only possible in a fully dual-stack\
      environment.\
\
   o  The client node may then be IPv6-only and receive IPv4\
      configuration settings that it does not want or be able to handle\
      meaningfully.\
\
   o  The DHCPv4 servers need to be configured anyway to support IPv4-\
      only hosts, so there is still duplication of information.\
\
   o  What happens if there are DHCPv6 servers that don't return IPv4\
      information?  Does this mean the client can't run IPv4 (since it\
      won't do DHCPv4)?\
\
   o  If IPv4 information is served from a DHCPv6 server as well as an\
      IPv4 DHCP server, IPv4 address space will need to be allocated to\
      both servers, fragmenting the potentially precious IPv4 global\
      address resource for the site.\
\
4.3.  Optimising for Failure with Lists of Addresses\
\
   There is a generic issue with any option that includes a list of\
   addresses of servers (such as DNS server addresses).  The list is\
   offered to cater for resilience, such as whether the listed server\
   itself fails or connectivity to the server fails.  If the client does\
   not know the cause of failure, its optimal strategy is to try a\
   different server, via a different protocol.  The problem today is\
   that the IPv4 list is returned via DHCPv4, and the IPv6 list via\
   DHCPv6; the client really has no way to "try a different server",\
   since that information is lost by the protocol, even though it may be\
   known by the server.\
\
   Just putting merging heuristics in the client cannot provide the best\
   behaviour, since information is lost.  By comparison, if IPv4-mapped\
   addresses were included in the DHCPv6 option along with IPv6\
   addresses, the DHCP server can give an intelligent order that takes\
   into account which addresses are of the same DNS/whatever server.\
   IPv6-only clients have to know to discard the IPv4-mapped addresses\
   in this solution, and it's much easier to solve this in the combined-\
   DHCP-server case than in the two-server case.\
\
\
\
Chown, et al.                Informational                      [Page 9]\
\
RFC 4477                DHCP: Dual-Stack Issues                 May 2006\
\
\
   One can argue that this is only an optimisation, and in many cases\
   the list has only two elements, so the "next" choice is forced.\
   However, this particular issue highlights the subtleties of merging\
   responses from separate servers.\
\
4.4.  Administrative and Other Areas\
\
   There are also administrative issues or best practice that could be\
   promoted.  For example, it may be recommended that sites do not split\
   their DNS name space for IPv6-specific testbeds.\
\
   It may be worth considering whether separate manual configuration\
   files should be kept for IPv4 and IPv6 settings, such as separate\
   /etc/resolv.conf files for DNS settings on UNIX systems.  However,\
   this seems a complex solution.  The problem should be better solved\
   by other, more generalised methods.\
\
   It may be important at times to be able to distinguish DHCP client\
   and server identities.  DHCPv6 introduces the idea of a DHCP Unique\
   Identifier (DUID).  The DUID concept has also been retrofitted to\
   DHCPv4 [6], and thus it may form the basis of part of the solution\
   space for the problem at hand.\
\
   Some differences in DHCP and DHCPv6 may not be reconciled, but may\
   not need to be, such as different ways to assign addresses by DUID in\
   DHCPv6, or the lack of a comparable option in both DHCP versions.\
\
5.  Summary\
\
   There are a number of issues in the operation of DHCP and DHCPv6\
   servers for nodes in dual-stack environments that should be\
   clarified.  While some differences in the protocols may not be\
   reconciled, there may not be a need to do so.  However, with DHCPv6\
   deployment growing, there is an operational requirement to determine\
   best practice for DHCP server provision in dual-stack environments,\
   which may or may not imply additional protocol requirements.  The\
   principal choice is whether separate DHCP and DHCPv6 services should\
   be maintained by a site, or whether DHCPv6 should be extended to\
   carry IPv4 configuration settings for dual-stack nodes.\
\
   It can certainly be argued that until a site is completely dual-\
   stack, an IPv4 DHCP service will always be required (for example,\
   while there are still legacy printers, IP webcams, or other devices\
   that still configure via DHCPv4), and a single IPv6 transport DHCP\
   server offering configuration information for both protocols will\
   then not be sufficient.  In that case, IPv4 DHCP is required, and\
   thus there\
\
\
\
\
Chown, et al.                Informational                     [Page 10]\
\
RFC 4477                DHCP: Dual-Stack Issues                 May 2006\
\
\
   is a good rationale for focusing effort on how to combine the\
   information received from separate IPv4 DHCP and (stateless) DHCPv6\
   servers.\
\
   In theory, it should be relatively straightforward to write a\
   configuration manager that would accept a single configuration\
   specification from the service manager and distribute the correct\
   (and consistent) configurations to the DHCPv4 and DHCPv6 servers\
   (whether on the same host or not).  In this case, maintaining\
   coordinated configurations in two servers is an interface issue, not\
   a protocol issue.  The question then is whether the client has all\
   the information it needs to make reasonable choices.  We are aware of\
   one implementation of separate DHCPv4 and DHCPv6 clients that is\
   using a preference option for assisting client-side merging of the\
   received information.\
\
   Another issue for discussion is whether a combined DHCP service only\
   available over IPv6 transport is a desirable longer-term goal for\
   networks containing only dual-stack or IPv6-only nodes (or IPv4-only\
   nodes where DHCPv4 is not needed).  The transition to the long-term\
   position may easily take more than 10 years.\
\
   Upon reflection on the above observations, the dhc WG reached a\
   strong consensus to adopt the two-server approach (separate DHCP and\
   DHCPv6 servers), rather than have a combined single server returning\
   IPv4 information over IPv6.  The two servers may be co-located on a\
   single node and may have consistent configuration information\
   generated from a single asset database.\
\
   It should be noted that deployment experience of DHCPv6 is still in\
   its infancy; thus, a full understanding of the issues may only\
   develop over time, but we feel we have reached the best consensus\
   given the current status.  Future work is now required to determine\
   best practice for merging information from multiple servers,\
   including merger of lists of addresses where options carry such\
   information.\
\
   As a footnote, we note that this work has overlap with multihoming\
   and multi-interface configuration issues.  It is also interwoven with\
   the Detecting Network Attachment area, for example, where a node may\
   move from an IPv4-only network to a dual-stack network, or vice\
   versa.  Both aspects may be best abstracted for discussion and\
   progression in the respective IETF multi6, shim6, and dna WGs, in\
   parallel with the two-server progression in the dhc WG.\
\
\
\
\
\
\
\
Chown, et al.                Informational                     [Page 11]\
\
RFC 4477                DHCP: Dual-Stack Issues                 May 2006\
\
\
6.  Security Considerations\
\
   There are no security considerations in this problem statement per\
   se, as it does not propose a new protocol.\
\
7.  Acknowledgements\
\
   The authors thank the following people for input to this document:\
   Bernie Volz, AK Vijayabhaskar, Ted Lemon, Ralph Droms, Robert Elz,\
   Changming Liu, Margaret Wasserman, Dave Thaler, Mark Hollinger, and\
   Greg Daley.  The document may not necessarily fully reflect the views\
   of each of these individuals.\
\
   The authors would also like to thank colleagues on the 6NET project\
   for contributions to this document.\
\
8.  Informative References\
\
   [1]  Droms, R., "Dynamic Host Configuration Protocol", RFC 2131,\
        March 1997.\
\
   [2]  Thomson, S. and T. Narten, "IPv6 Stateless Address\
        Autoconfiguration", RFC 2462, December 1998.\
\
   [3]  Droms, R. and W. Arbaugh, "Authentication for DHCP Messages",\
        RFC 3118, June 2001.\
\
   [4]  Droms, R., Bound, J., Volz, B., Lemon, T., Perkins, C., and M.\
        Carney, "Dynamic Host Configuration Protocol for IPv6 (DHCPv6)",\
        RFC 3315, July 2003.\
\
   [5]  Droms, R., "Stateless Dynamic Host Configuration Protocol (DHCP)\
        Service for IPv6", RFC 3736, April 2004.\
\
   [6]  Lemon, T. and B. Sommerfeld, "Node-specific Client Identifiers\
        for Dynamic Host Configuration Protocol Version Four (DHCPv4)",\
        RFC 4361, February 2006.\
\
\
\
\
\
\
\
\
\
\
\
\
\
\
Chown, et al.                Informational                     [Page 12]\
\
RFC 4477                DHCP: Dual-Stack Issues                 May 2006\
\
\
Authors' Addresses\
\
   Tim Chown\
   University of Southampton\
   School of Electronics and Computer Science\
   Southampton, Hampshire  SO17 1BJ\
   United Kingdom\
\
   EMail: tjc@ecs.soton.ac.uk\
\
\
   Stig Venaas\
   UNINETT\
   Trondheim  NO 7465\
   Norway\
\
   EMail: venaas@uninett.no\
\
\
   Christian Strauf\
   Clausthal University of Technology\
   Erzstr. 51\
   Clausthal-Zellerfeld  D-38678\
   Germany\
\
   EMail: strauf@rz.tu-clausthal.de\
\
\
\
\
\
\
\
\
\
\
\
\
\
\
\
\
\
\
\
\
\
\
\
\
\
Chown, et al.                Informational                     [Page 13]\
\
RFC 4477                DHCP: Dual-Stack Issues                 May 2006\
\
\
Full Copyright Statement\
\
   Copyright (C) The Internet Society (2006).\
\
   This document is subject to the rights, licenses and restrictions\
   contained in BCP 78, and except as set forth therein, the authors\
   retain all their rights.\
\
   This document and the information contained herein are provided on an\
   "AS IS" basis and THE CONTRIBUTOR, THE ORGANIZATION HE/SHE REPRESENTS\
   OR IS SPONSORED BY (IF ANY), THE INTERNET SOCIETY AND THE INTERNET\
   ENGINEERING TASK FORCE DISCLAIM ALL WARRANTIES, EXPRESS OR IMPLIED,\
   INCLUDING BUT NOT LIMITED TO ANY WARRANTY THAT THE USE OF THE\
   INFORMATION HEREIN WILL NOT INFRINGE ANY RIGHTS OR ANY IMPLIED\
   WARRANTIES OF MERCHANTABILITY OR FITNESS FOR A PARTICULAR PURPOSE.\
\
Intellectual Property\
\
   The IETF takes no position regarding the validity or scope of any\
   Intellectual Property Rights or other rights that might be claimed to\
   pertain to the implementation or use of the technology described in\
   this document or the extent to which any license under such rights\
   might or might not be available; nor does it represent that it has\
   made any independent effort to identify any such rights.  Information\
   on the procedures with respect to rights in RFC documents can be\
   found in BCP 78 and BCP 79.\
\
   Copies of IPR disclosures made to the IETF Secretariat and any\
   assurances of licenses to be made available, or the result of an\
   attempt made to obtain a general license or permission for the use of\
   such proprietary rights by implementers or users of this\
   specification can be obtained from the IETF on-line IPR repository at\
   http://www.ietf.org/ipr.\
\
   The IETF invites any interested party to bring to its attention any\
   copyrights, patents or patent applications, or other proprietary\
   rights that may cover technology that may be required to implement\
   this standard.  Please address the information to the IETF at\
   ietf-ipr@ietf.org.\
\
Acknowledgement\
\
   Funding for the RFC Editor function is provided by the IETF\
   Administrative Support Activity (IASA).\
\
\
\
\
\
\
\
Chown, et al.                Informational                     [Page 14]\
\

doc 16
  field 0
    name titolo
    type string
    value rfc4469.txt
  field 1
    name contenuto
    type string
    value \
\
\
\
\
\
Network Working Group                                         P. Resnick\
Request for Comments: 4469                         QUALCOMM Incorporated\
Updates: 3501, 3502                                           April 2006\
Category: Standards Track\
\
\
       Internet Message Access Protocol (IMAP) CATENATE Extension\
\
Status of This Memo\
\
   This document specifies an Internet standards track protocol for the\
   Internet community, and requests discussion and suggestions for\
   improvements.  Please refer to the current edition of the "Internet\
   Official Protocol Standards" (STD 1) for the standardization state\
   and status of this protocol.  Distribution of this memo is unlimited.\
\
Copyright Notice\
\
   Copyright (C) The Internet Society (2006).\
\
Abstract\
\
   The CATENATE extension to the Internet Message Access Protocol (IMAP)\
   extends the APPEND command to allow clients to create messages on the\
   IMAP server that may contain a combination of new data along with\
   parts of (or entire) messages already on the server.  Using this\
   extension, the client can catenate parts of an already existing\
   message onto a new message without having to first download the data\
   and then upload it back to the server.\
\
\
\
\
\
\
\
\
\
\
\
\
\
\
\
\
\
\
\
\
\
\
Resnick                     Standards Track                     [Page 1]\
\
RFC 4469                IMAP CATENATE Extension               April 2006\
\
\
1.  Introduction\
\
   The CATENATE extension to the Internet Message Access Protocol (IMAP)\
   [1] allows the client to create a message on the server that can\
   include the text of messages (or parts of messages) that already\
   exist on the server without having to FETCH them and APPEND them back\
   to the server.  The CATENATE extension extends the APPEND command so\
   that, instead of a single message literal, the command can take as\
   arguments any combination of message literals (as described in IMAP\
   [1]) and message URLs (as described in the IMAP URL Scheme [2]\
   specification).  The server takes all the pieces and catenates them\
   into the output message.  The CATENATE extension can also coexist\
   with the MULTIAPPEND extension [3] to APPEND multiple messages in a\
   single command.\
\
   There are some obvious uses for the CATENATE extension.  The\
   motivating use case was to provide a way for a resource-constrained\
   client to compose a message for subsequent submission that contains\
   data that already exists in that client's IMAP store.  Because the\
   client does not have to download and re-upload potentially large\
   message parts, bandwidth and processing limitations do not have as\
   much impact.  In addition, since the client can create a message in\
   its own IMAP store, the command also addresses the desire of the\
   client to archive a copy of a sent message without having to upload\
   the message twice.  (Mechanisms for sending the message are outside\
   the scope of this document.)\
\
   The extended APPEND command can also be used to copy parts of a\
   message to another mailbox for archival purposes while getting rid of\
   undesired parts.  In environments where server storage is limited, a\
   client could get rid of large message parts by copying over only the\
   necessary parts and then deleting the original message.  The\
   mechanism could also be used to add data to a message (such as\
   prepending message header fields) or to include other data by making\
   a copy of the original and catenating the new data.\
\
2.  The CATENATE Capability\
\
   A server that supports this extension returns "CATENATE" as one of\
   the responses to the CAPABILITY command.\
\
\
\
\
\
\
\
\
\
\
\
Resnick                     Standards Track                     [Page 2]\
\
RFC 4469                IMAP CATENATE Extension               April 2006\
\
\
3.  The APPEND Command\
\
   Arguments:  mailbox name\
               (The following can be repeated in the presence of the\
               MULTIAPPEND extension [3])\
               OPTIONAL flag parenthesized list\
               OPTIONAL date/time string\
               a single message literal or one or more message parts to\
               catenate, specified as:\
                           message literal\
                           or\
                           message (or message part) URL\
\
   Responses:  OPTIONAL NO responses: BADURL, TOOBIG\
\
   Result:     OK -  append completed\
               NO -  append error: can't append to that mailbox, error\
                     in flags or date/time or message text, or can't\
                     fetch that data\
               BAD - command unknown or arguments invalid\
\
   The APPEND command concatenates all the message parts and appends\
   them as a new message to the end of the specified mailbox.  The\
   parenthesized flag list and date/time string set the flags and the\
   internal date, respectively, as described in IMAP [1].  The\
   subsequent command parameters specify the message parts that are\
   appended sequentially to the output message.\
\
   If the original form of APPEND is used, a message literal follows the\
   optional flag list and date/time string, which is appended as\
   described in IMAP [1].  If the extended form is used, "CATENATE" and\
   a parenthesized list of message literals and message URLs follows,\
   each of which is appended to the new message.  If a message literal\
   is specified (indicated by "TEXT"), the octets following the count\
   are appended.  If a message URL is specified (indicated by "URL"),\
   the octets of the body part pointed to by that URL are appended, as\
   if the literal returned in a FETCH BODY response were put in place of\
   the message part specifier.  The APPEND command does not cause the\
   \\Seen flag to be set for any catenated body part.  The APPEND command\
   does not change the selected mailbox.\
\
   In the extended APPEND command, the string following "URL" is an IMAP\
   URL [2] and is interpreted according to the rules of [2].  The\
   present document only describes the behavior of the command using\
   IMAP URLs that refer to specific messages or message parts on the\
   current IMAP server from the current authenticated IMAP session.\
   Because of that, only relative IMAP message or message part URLs\
   (i.e., those having no scheme or <iserver>) are used.  The base URL\
\
\
\
Resnick                     Standards Track                     [Page 3]\
\
RFC 4469                IMAP CATENATE Extension               April 2006\
\
\
   for evaluating the relative URL is considered "imap://user@server/",\
   where "user" is the user name of the currently authenticated user and\
   "server" is the domain name of the current server.  When in the\
   selected state, the base URL is considered\
   "imap://user@server/mailbox", where "mailbox" is the encoded name of\
   the currently selected mailbox.  Additionally, since the APPEND\
   command is valid in the authenticated state of an IMAP session, no\
   further LOGIN or AUTHENTICATE command is performed for URLs specified\
   in the extended APPEND command.\
\
      Note: Use of an absolute IMAP URL or any URL that refers to\
      anything other than a message or message part from the current\
      authenticated IMAP session is outside the scope of this document\
      and would require an extension to this specification, and a server\
      implementing only this specification would return NO to such a\
      request.\
\
   The client is responsible for making sure that the catenated message\
   is in the format of an Internet Message Format (RFC 2822) [4] or\
   Multipurpose Internet Mail Extension (MIME) [5] message.  In\
   particular, when a URL is catenated, the server copies octets,\
   unchanged, from the indicated message or message part to the\
   catenated message.  It does no data conversion (e.g., MIME transfer\
   encodings) nor any verification that the data is appropriate for the\
   MIME part of the message into which it is inserted.  The client is\
   also responsible for inserting appropriate MIME boundaries between\
   body parts, and writing MIME Content-Type and Content-Transfer-\
   Encoding lines as needed in the appropriate places.\
\
   Responses behave just as the original APPEND command described in\
   IMAP [1].  If the server implements the IMAP UIDPLUS extension [6],\
   it will also return an APPENDUID response code in the tagged OK\
   response.  Two response codes are provided in Section 4 that can be\
   used in the tagged NO response if the APPEND command fails.\
\
4.  Response Codes\
\
   When a APPEND command fails, it may return a response code that\
   describes a reason for the failure.\
\
4.1.  BADURL Response\
\
   The BADURL response code is returned if the APPEND fails to process\
   one of the specified URLs.  Possible reasons for this are bad URL\
   syntax, unrecognized URL schema, invalid message UID, or invalid body\
   part.  The BADURL response code contains the first URL specified as a\
   parameter to the APPEND command that has caused the operation to\
   fail.\
\
\
\
Resnick                     Standards Track                     [Page 4]\
\
RFC 4469                IMAP CATENATE Extension               April 2006\
\
\
4.2.  TOOBIG Response\
\
   The TOOBIG response code is returned if the resulting message will\
   exceed the 4-GB IMAP message limit.  This might happen, for example,\
   if the client specifies 3 URLs for 2-GB messages.  Note that even if\
   the server doesn't return TOOBIG, it still has to be defensive\
   against misbehaving or malicious clients that try to construct a\
   message over the 4-GB limit.  The server may also wish to return the\
   TOOBIG response code if the resulting message exceeds a server-\
   specific message size limit.\
\
5.  Formal Syntax\
\
   The following syntax specification uses the Augmented Backus-Naur\
   Form (ABNF) [7] notation.  Elements not defined here can be found in\
   the formal syntax of the ABNF [7], IMAP [1], and IMAP ABNF extensions\
   [8] specifications.  Note that capability and resp-text-code are\
   extended from the IMAP [1] specification and append-data is extended\
   from the IMAP ABNF extensions [8] specification.\
\
   append-data =/ "CATENATE" SP "(" cat-part *(SP cat-part) ")"\
\
   cat-part = text-literal / url\
\
   text-literal = "TEXT" SP literal\
\
   url = "URL" SP astring\
\
   resp-text-code =/ toobig-response-code / badurl-response-code\
\
   toobig-response-code = "TOOBIG"\
\
   badurl-response-code = "BADURL" SP url-resp-text\
\
   url-resp-text = 1*(%x01-09 /\
                      %x0B-0C /\
                      %x0E-5B /\
                      %x5D-FE) ; Any TEXT-CHAR except "]"\
\
   capability =/ "CATENATE"\
\
   The astring in the definition of url and the url-resp-text in the\
   definition of badurl-response-code each contain an imapurl as defined\
   by [2].\
\
\
\
\
\
\
\
Resnick                     Standards Track                     [Page 5]\
\
RFC 4469                IMAP CATENATE Extension               April 2006\
\
\
6.  Acknowledgements\
\
   Thanks to the members of the LEMONADE working group for their input.\
   Special thanks to Alexey Melnikov for the examples.\
\
7.  Security Considerations\
\
   The CATENATE extension does not raise any security considerations\
   that are not present for the base protocol or in the use of IMAP\
   URLs, and these issues are discussed in the IMAP [1] and IMAP URL [2]\
   documents.\
\
8.  IANA Considerations\
\
   IMAP4 capabilities are registered by publishing a standards track or\
   IESG approved experimental RFC.  The registry is currently located at\
   <http://www.iana.org/assignments/imap4-capabilities>.  This document\
   defines the CATENATE IMAP capability.  The IANA has added this\
   capability to the registry.\
\
\
\
\
\
\
\
\
\
\
\
\
\
\
\
\
\
\
\
\
\
\
\
\
\
\
\
\
\
\
\
\
Resnick                     Standards Track                     [Page 6]\
\
RFC 4469                IMAP CATENATE Extension               April 2006\
\
\
Appendix A.  Examples\
\
   Lines not starting with "C: " or "S: " are continuations of the\
   previous lines.\
\
   The original message in examples 1 and 2 below (UID = 20) has the\
   following structure:\
\
\
      multipart/mixed MIME message with two body parts:\
\
      1.  text/plain\
\
      2.  application/x-zip-compressed\
\
   Example 1: The following example demonstrates how a CATENATE client\
   can replace an attachment in a draft message, without the need to\
   download it to the client and upload it back.\
\
   C: A003 APPEND Drafts (\\Seen \\Draft $MDNSent) CATENATE\
    (URL "/Drafts;UIDVALIDITY=385759045/;UID=20/;section=HEADER"\
    TEXT {42}\
   S: + Ready for literal data\
   C:\
   C: --------------030308070208000400050907\
   C:  URL "/Drafts;UIDVALIDITY=385759045/;UID=20/;section=1.MIME"\
    URL "/Drafts;UIDVALIDITY=385759045/;UID=20/;section=1" TEXT {42}\
   S: + Ready for literal data\
   C:\
   C: --------------030308070208000400050907\
   C:  URL "/Drafts;UIDVALIDITY=385759045/;UID=30" TEXT {44}\
   S: + Ready for literal data\
   C:\
   C: --------------030308070208000400050907--\
   C: )\
   S: A003 OK catenate append completed\
\
\
\
\
\
\
\
\
\
\
\
\
\
\
\
Resnick                     Standards Track                     [Page 7]\
\
RFC 4469                IMAP CATENATE Extension               April 2006\
\
\
   Example 2: The following example demonstrates how the CATENATE\
   extension can be used to replace edited text in a draft message, as\
   well as header fields for the top level message part (e.g., Subject\
   has changed).  The previous version of the draft is marked as\
   \\Deleted.  Note that the server also supports the UIDPLUS extension,\
   so the APPENDUID response code is returned in the successful OK\
   response to the APPEND command.\
\
   C: A003 APPEND Drafts (\\Seen \\Draft $MDNSent) CATENATE (TEXT {738}\
   S: + Ready for literal data\
   C: Return-Path: <bar@example.org>\
   C: Received: from [127.0.0.2]\
   C:           by rufus.example.org via TCP (internal) with ESMTPA;\
   C:           Thu, 11 Nov 2004 16:57:07 +0000\
   C: Message-ID: <419399E1.6000505@example.org>\
   C: Date: Thu, 12 Nov 2004 16:57:05 +0000\
   C: From: Bob Ar <bar@example.org>\
   C: X-Accept-Language: en-us, en\
   C: MIME-Version: 1.0\
   C: To: foo@example.net\
   C: Subject: About our holiday trip\
   C: Content-Type: multipart/mixed;\
   C:               boundary="------------030308070208000400050907"\
   C:\
   C: --------------030308070208000400050907\
   C: Content-Type: text/plain; charset=us-ascii; format=flowed\
   C: Content-Transfer-Encoding: 7bit\
   C:\
   C: Our travel agent has sent the updated schedule.\
   C:\
   C: Cheers,\
   C: Bob\
   C: --------------030308070208000400050907\
   C:  URL "/Drafts;UIDVALIDITY=385759045/;UID=20/;Section=2.MIME"\
    URL "/Drafts;UIDVALIDITY=385759045/;UID=20/;Section=2" TEXT {44}\
   S: + Ready for literal data\
   C:\
   C: --------------030308070208000400050907--\
   C: )\
   S: A003 OK [APPENDUID 385759045 45] append Completed\
   C: A004 UID STORE 20 +FLAGS.SILENT (\\Deleted)\
   S: A004 OK STORE completed\
\
\
\
\
\
\
\
\
\
Resnick                     Standards Track                     [Page 8]\
\
RFC 4469                IMAP CATENATE Extension               April 2006\
\
\
   Example 3: The following example demonstrates how the CATENATE\
   extension can be used to strip attachments.  Below, a PowerPoint\
   attachment was replaced by a small text part explaining that the\
   attachment was stripped.\
\
   C: A003 APPEND Drafts (\\Seen \\Draft $MDNSent) CATENATE\
    (URL "/Drafts;UIDVALIDITY=385759045/;UID=21/;section=HEADER"\
    TEXT {42}\
   S: + Ready for literal data\
   C:\
   C: --------------030308070208000400050903\
   C:  URL "/Drafts;UIDVALIDITY=385759045/;UID=21/;section=1.MIME"\
    URL "/Drafts;UIDVALIDITY=385759045/;UID=21/;section=1" TEXT {255}\
   S: + Ready for literal data\
   C:\
   C: --------------030308070208000400050903\
   C: Content-type: text/plain; charset="us-ascii"\
   C: Content-transfer-encoding: 7bit\
   C:\
   C: This body part contained a Power Point presentation that was\
   C: deleted upon your request.\
   C: --------------030308070208000400050903--\
   C: )\
   S: A003 OK append Completed\
\
\
\
\
\
\
\
\
\
\
\
\
\
\
\
\
\
\
\
\
\
\
\
\
\
\
\
Resnick                     Standards Track                     [Page 9]\
\
RFC 4469                IMAP CATENATE Extension               April 2006\
\
\
   Example 4: The following example demonstrates a failed APPEND\
   command.  The server returns the BADURL response code to indicate\
   that one of the provided URLs is invalid.  This example also\
   demonstrates how the CATENATE extension can be used to construct a\
   digest of several messages.\
\
   C: A003 APPEND Sent (\\Seen $MDNSent) CATENATE (TEXT {541}\
   S: + Ready for literal data\
   C: Return-Path: <foo@example.org>\
   C: Received: from [127.0.0.2]\
   C:           by rufus.example.org via TCP (internal) with ESMTPA;\
   C:           Thu, 11 Nov 2004 16:57:07 +0000\
   C: Message-ID: <419399E1.6000505@example.org>\
   C: Date: Thu, 21 Nov 2004 16:57:05 +0000\
   C: From: Farren Oo <foo@example.org>\
   C: X-Accept-Language: en-us, en\
   C: MIME-Version: 1.0\
   C: To: bar@example.org\
   C: Subject: Digest of the mailing list for today\
   C: Content-Type: multipart/digest;\
   C:               boundary="------------030308070208000400050904"\
   C:\
   C: --------------030308070208000400050904\
   C:  URL "/INBOX;UIDVALIDITY=785799047/;UID=11467" TEXT {42}\
   S: + Ready for literal data\
   C:\
   C: --------------030308070208000400050904\
   C:  URL "/INBOX;UIDVALIDITY=785799047/;UID=113330/;section=1.5.9"\
    TEXT {42}\
   S: + Ready for literal data\
   C:\
   C: --------------030308070208000400050904\
   C:  URL "/INBOX;UIDVALIDITY=785799047/;UID=11916" TEXT {44}\
   S: + Ready for literal data\
   C:\
   C: --------------030308070208000400050904--\
   C: )\
   S: A003 NO [BADURL "/INBOX;UIDVALIDITY=785799047/;UID=113330;\
   section=1.5.9"] CATENATE append has failed, one message expunged\
\
   Note that the server could have validated the URLs as they were\
   received and therefore could have returned the tagged NO response\
   with BADURL response-code in place of any continuation request after\
   the URL was received.\
\
\
\
\
\
\
\
Resnick                     Standards Track                    [Page 10]\
\
RFC 4469                IMAP CATENATE Extension               April 2006\
\
\
9.  Normative References\
\
   [1]  Crispin, M., "INTERNET MESSAGE ACCESS PROTOCOL - VERSION 4rev1",\
        RFC 3501, March 2003.\
\
   [2]  Newman, C., "IMAP URL Scheme", RFC 2192, September 1997.\
\
   [3]  Crispin, M., "Internet Message Access Protocol (IMAP) -\
        MULTIAPPEND Extension", RFC 3502, March 2003.\
\
   [4]  Resnick, P., "Internet Message Format", RFC 2822, April 2001.\
\
   [5]  Freed, N. and N. Borenstein, "Multipurpose Internet Mail\
        Extensions (MIME) Part One: Format of Internet Message Bodies",\
        RFC 2045, November 1996.\
\
   [6]  Crispin, M., "Internet Message Access Protocol (IMAP) - UIDPLUS\
        extension", RFC 4315, December 2005.\
\
   [7]  Crocker, D. and P. Overell, "Augmented BNF for Syntax\
        Specifications: ABNF", RFC 4234, October 2005.\
\
   [8]  Melnikov, A. and C. Daboo, "Collected Extensions to IMAP4 ABNF",\
        RFC 4466, April 2006.\
\
\
\
\
\
\
\
\
\
\
\
\
\
\
\
\
\
\
\
\
\
\
\
\
\
\
\
Resnick                     Standards Track                    [Page 11]\
\
RFC 4469                IMAP CATENATE Extension               April 2006\
\
\
Author's Address\
\
   Peter W. Resnick\
   QUALCOMM Incorporated\
   5775 Morehouse Drive\
   San Diego, CA  92121-1714\
   US\
\
   Phone: +1 858 651 4478\
   EMail: presnick@qualcomm.com\
   URI:   http://www.qualcomm.com/~presnick/\
\
\
\
\
\
\
\
\
\
\
\
\
\
\
\
\
\
\
\
\
\
\
\
\
\
\
\
\
\
\
\
\
\
\
\
\
\
\
\
\
Resnick                     Standards Track                    [Page 12]\
\
RFC 4469                IMAP CATENATE Extension               April 2006\
\
\
Full Copyright Statement\
\
   Copyright (C) The Internet Society (2006).\
\
   This document is subject to the rights, licenses and restrictions\
   contained in BCP 78, and except as set forth therein, the authors\
   retain all their rights.\
\
   This document and the information contained herein are provided on an\
   "AS IS" basis and THE CONTRIBUTOR, THE ORGANIZATION HE/SHE REPRESENTS\
   OR IS SPONSORED BY (IF ANY), THE INTERNET SOCIETY AND THE INTERNET\
   ENGINEERING TASK FORCE DISCLAIM ALL WARRANTIES, EXPRESS OR IMPLIED,\
   INCLUDING BUT NOT LIMITED TO ANY WARRANTY THAT THE USE OF THE\
   INFORMATION HEREIN WILL NOT INFRINGE ANY RIGHTS OR ANY IMPLIED\
   WARRANTIES OF MERCHANTABILITY OR FITNESS FOR A PARTICULAR PURPOSE.\
\
Intellectual Property\
\
   The IETF takes no position regarding the validity or scope of any\
   Intellectual Property Rights or other rights that might be claimed to\
   pertain to the implementation or use of the technology described in\
   this document or the extent to which any license under such rights\
   might or might not be available; nor does it represent that it has\
   made any independent effort to identify any such rights.  Information\
   on the procedures with respect to rights in RFC documents can be\
   found in BCP 78 and BCP 79.\
\
   Copies of IPR disclosures made to the IETF Secretariat and any\
   assurances of licenses to be made available, or the result of an\
   attempt made to obtain a general license or permission for the use of\
   such proprietary rights by implementers or users of this\
   specification can be obtained from the IETF on-line IPR repository at\
   http://www.ietf.org/ipr.\
\
   The IETF invites any interested party to bring to its attention any\
   copyrights, patents or patent applications, or other proprietary\
   rights that may cover technology that may be required to implement\
   this standard.  Please address the information to the IETF at\
   ietf-ipr@ietf.org.\
\
Acknowledgement\
\
   Funding for the RFC Editor function is provided by the IETF\
   Administrative Support Activity (IASA).\
\
\
\
\
\
\
\
Resnick                     Standards Track                    [Page 13]\
\

doc 17
  field 0
    name titolo
    type string
    value rfc4476.txt
  field 1
    name contenuto
    type string
    value \
\
\
\
\
\
Network Working Group                                         C. Francis\
Request for Comments: 4476                                      Raytheon\
Category: Standards Track                                      D. Pinkas\
                                                                    Bull\
                                                                May 2006\
\
\
             Attribute Certificate (AC) Policies Extension\
\
Status of This Memo\
\
   This document specifies an Internet standards track protocol for the\
   Internet community, and requests discussion and suggestions for\
   improvements.  Please refer to the current edition of the "Internet\
   Official Protocol Standards" (STD 1) for the standardization state\
   and status of this protocol.  Distribution of this memo is unlimited.\
\
Copyright Notice\
\
   Copyright (C) The Internet Society (2006).\
\
Abstract\
\
   This document describes one certificate extension that explicitly\
   states the Attribute Certificate Policies (ACPs) that apply to a\
   given Attribute Certificate (AC).  The goal of this document is to\
   allow relying parties to perform an additional test when validating\
   an AC, i.e., to assess whether a given AC carrying some attributes\
   can be accepted on the basis of references to one or more specific\
   ACPs.\
\
\
\
\
\
\
\
\
\
\
\
\
\
\
\
\
\
\
\
\
\
Francis & Pinkas            Standards Track                     [Page 1]\
\
RFC 4476                 AC Policies Extension                  May 2006\
\
\
1.  Introduction\
\
   When issuing a Public Key Certificate (PKC), a Certificate Authority\
   (CA) can perform various levels of verification with regard to the\
   subject identity (see [RFC3280]).  A CA makes its verification\
   procedures, as well as other operational rules it abides by,\
   "visible" through a certificate policy, which may be referenced by a\
   certificate policies extension in the PKC.\
\
   The purpose of this document is to define an Attribute Certificate\
   (AC) policies extension able to explicitly state the AC policies that\
   apply to a given AC, but not the AC policies themselves.  Attribute\
   Certificates are defined in [RFC3281].\
\
1.1.  Conventions Used in This Document\
\
   The key words "MUST", "MUST NOT", "REQUIRED", "SHALL", "SHALL NOT",\
   "SHOULD", "SHOULD NOT", "RECOMMENDED", "MAY", and "OPTIONAL" in this\
   document are to be interpreted as described in [RFC2119].\
\
2.  AC Policies Extension Semantics\
\
   An Attribute Certificate Policy is a named set of rules that\
   indicates the applicability of an AC to a particular community and/or\
   class of applications with common security requirements.  It defines\
   rules for the generation, issuance, and revocation of ACs.  It may\
   also include additional rules for attributes registration.\
\
   Thus, note that an Attribute Authority (AA) does not necessarily\
   support one single ACP.  However, for each AC that is delivered, the\
   AA SHALL make sure that the policy applies to all the attributes that\
   are contained in it.\
\
   An ACP may be used by an AC user to decide whether or not to trust\
   the attributes contained in an AC for a particular purpose.\
\
   When an AC contains an AC policies extension, the extension MAY, at\
   the option of the AA, be either critical or non-critical.\
\
   The AC Policies extension MAY be included in an AC.  Like all X.509\
   certificate extensions [X.509], the AC policies extension is defined\
   using ASN.1 [ASN1].  See Appendix A.\
\
   The definitions are presented in the 1988 Abstract Syntax Notation\
   One (ASN.1) rather than the 1997 ASN.1 syntax used in the most recent\
   ISO/IEC/ITU-T standards.\
\
   The AC policies extension is identified by id-pe-acPolicies.\
\
\
\
Francis & Pinkas            Standards Track                     [Page 2]\
\
RFC 4476                 AC Policies Extension                  May 2006\
\
\
      id-pe-acPolicies OBJECT IDENTIFIER ::= { iso(1)\
        identified-organization(3) dod(6) internet(1) security(5)\
        mechanisms(5) id-pkix(7) id-pe(1) 15 }\
\
   The AC policies extension includes a list of AC policies recognized\
   by the AA that apply to the attributes included in the AC.\
\
   AC Policies may be defined by any organization with a need.  Object\
   identifiers used to identify AC Policies are assigned in accordance\
   with [X.660|ISO9834-1].\
\
   The AC policies extension in an AC indicates the AC policies for\
   which the AC is valid.\
\
   An application that recognizes this extension and its content SHALL\
   process the extension regardless of the value of the criticality\
   flag.\
\
   If the extension is both flagged non-critical and not recognized by\
   the AC-using application, then the application MAY ignore it.\
\
   If the extension is marked critical or is recognized by the AC-using\
   application, it indicates that the attributes contained in the\
   attribute certificate SHALL only be used for the purpose, and in\
   accordance with the rules associated with one of the indicated AC\
   policies.  If none of the ACP identifiers is adequate for the\
   application, then the AC MUST be rejected.\
\
   If the extension is marked critical or is recognized by the AC using\
   application, the AC-using application MUST use the list of AC\
   policies to determine whether it is appropriate to use the attributes\
   contained in that AC for a particular transaction.  When the\
   appropriate policy is not found, the AC SHALL be rejected.\
\
2.1.  AC Policy Extension Syntax\
\
   The syntax for the AC Policy extension is:\
\
   AcPoliciesSyntax ::= SEQUENCE SIZE (1..MAX) OF PolicyInformation\
\
   PolicyInformation ::= SEQUENCE {\
       policyIdentifier      AcPolicyId,\
       policyQualifiers      SEQUENCE SIZE (1..MAX) OF\
                                      PolicyQualifierInfo OPTIONAL}\
\
   AcPolicyId ::= OBJECT IDENTIFIER\
\
\
\
\
\
Francis & Pinkas            Standards Track                     [Page 3]\
\
RFC 4476                 AC Policies Extension                  May 2006\
\
\
    PolicyQualifierInfo ::= SEQUENCE {\
         policyQualifierId  PolicyQualifierId,\
         qualifier          ANY DEFINED BY policyQualifierId }\
\
   -- policyQualifierIds for Internet policy qualifiers\
\
    id-qt            OBJECT IDENTIFIER ::=  { id-pkix 2 }\
    id-qt-acps       OBJECT IDENTIFIER ::=  { id-qt 4 }\
    id-qt-acunotice  OBJECT IDENTIFIER ::=  { id-qt 5 }\
\
    id-qt-acps OBJECT IDENTIFIER ::= { iso(1)\
      identified-organization(3) dod(6) internet(1) security(5)\
      mechanisms(5) id-pkix(7) id-qt(2) 4 }\
\
    id-qt-acunotice OBJECT IDENTIFIER ::= { iso(1)\
      identified-organization(3) dod(6) internet(1) security(5)\
      mechanisms(5) id-pkix(7) id-qt(2) 5 }\
\
    PolicyQualifierId ::=\
         OBJECT IDENTIFIER ( id-qt-acps | id-qt-acunotice )\
\
   -- ACPS pointer qualifier\
\
   ACPSuri ::= IA5String\
   -- ACP statement user notice qualifier\
\
   ACUserNotice ::= UserNotice\
   -- UserNotice is defined in [RFC3280]\
\
   To promote interoperability, this document RECOMMENDS that policy\
   information terms consist of only an object identifier (OID).  When\
   more than one policy is used, the policy requirements have to be\
   non-conflicting, e.g., one policy may refine the general requirements\
   mandated by another policy.\
\
   The extension defined in this specification supports two policy\
   qualifier types for use by ACP writers and AAs.  The qualifier types\
   are the ACPS Pointer and the AC User.\
\
2.1.1.  Notice Qualifiers\
\
   The ACPS Pointer qualifier contains a pointer to an Attribute\
   Certification Practice Statement (ACPS) published by the AA.  The\
   pointer is in the form of a URI.  Processing requirements for this\
   qualifier are a local matter.\
\
\
\
\
\
\
Francis & Pinkas            Standards Track                     [Page 4]\
\
RFC 4476                 AC Policies Extension                  May 2006\
\
\
   The AC User Notice is intended for display to a relying party when an\
   attribute certificate is used.  The application software SHOULD\
   display the AC User Notice of the AC.  The AC User Notice is defined\
   in [RFC3280].  It has two optional fields: the noticeRef field and\
   the explicitText field.\
\
      The noticeRef field, if used, names an organization and\
      identifies, by number, a particular textual statement prepared by\
      that organization.  For example, it might identify the\
      organization's name and notice number 1.  In a typical\
      implementation, the application software will have a notice file\
      containing the current set of notices for the AA; the application\
      will extract the notice text from the file and display it.\
      Messages MAY be multilingual, allowing the software to select the\
      particular language message for its own environment.\
\
      An explicitText field includes the textual statement directly in\
      the certificate.  The explicitText field is a string with a\
      maximum size of 200 characters.\
\
   If both the noticeRef and explicitText options are included in the\
   one qualifier, and if the application software can locate the notice\
   text indicated by the noticeRef option, then that text SHOULD be\
   displayed; otherwise, the explicitText string SHOULD be displayed.\
\
2.2.  Attribute Certificate Policies\
\
   The scope of this document is not the definition of the detailed\
   content of ACPs themselves; therefore, specific policies are not\
   defined in this document.\
\
3.  Security Considerations\
\
   The ACP defined in this document applies for all the attributes that\
   are included in one AC.  AAs SHALL ensure that the ACP applies to all\
   the attributes that are included in the ACs they issue.\
\
   Attributes may be dynamically grouped in several ACs.  It should be\
   observed that since an AC may be issued under more than one ACP, the\
   attributes included in a given AC MUST be compliant with all the ACPs\
   from that AC.\
\
   When verifying an AC, a relying party MUST determine that the AC was\
   issued by a trusted AA and then that it has the appropriate policy.\
\
\
\
\
\
\
\
Francis & Pinkas            Standards Track                     [Page 5]\
\
RFC 4476                 AC Policies Extension                  May 2006\
\
\
   Failure of AAs to protect their private keys will permit an attacker\
   to masquerade as them, potentially generating false ACs or revocation\
   status.  Existence of bogus ACs and revocation status will undermine\
   confidence in the system.  If the compromise is detected, then the\
   certificate of the AA MUST be revoked.\
\
   Rebuilding after such a compromise will be problematic, so AAs are\
   advised to implement a combination of strong technical measures\
   (e.g., tamper-resistant cryptographic modules) and appropriate\
   management procedures (e.g., separation of duties) to avoid such an\
   incident.\
\
   Loss of an AA's private signing key may also be problematic.  The AA\
   would not be able to produce revocation status or perform AC renewal\
   (i.e., the issue of a new AC with the same set of attributes with the\
   same values, for the same holder, from the same AA but with a\
   different validity period).  AC issuers are advised to maintain\
   secure backup for signing keys.  The security of the key backup\
   procedures is a critical factor in avoiding key compromise.\
\
   The availability and freshness of revocation status will affect the\
   degree of assurance that should be placed in a long-lived AC.  While\
   long-lived ACs expire naturally, events may occur during an AC's\
   natural lifetime that negate the binding between the AC holder and\
   the attributes.  If revocation status is untimely or unavailable, the\
   assurance associated with the binding is clearly reduced.\
\
   The binding between an AC holder and attributes cannot be stronger\
   than the cryptographic module implementation and algorithms used to\
   generate the signature.  Short key lengths or weak hash algorithms\
   will limit the utility of an AC.  AAs are encouraged to note advances\
   in cryptology so they can employ strong cryptographic techniques.\
\
   If an AC is tied to the holder's PKC using the baseCertificateID\
   component of the Holder field and the PKI in use includes a rogue CA\
   with the same issuer name specified in the baseCertificateID\
   component, this rogue CA could issue a PKC to a malicious party,\
   using the same issuer name and serial number as the proper holder's\
   PKC.  Then the malicious party could use this PKC in conjunction with\
   the AC.  This scenario SHOULD be avoided by properly managing and\
   configuring the PKI so that there cannot be two CAs with the same\
   name.  Another alternative is to tie ACs to PKCs using the\
   publicKeyCert type in the ObjectDigestInfo field.  Failing this, AC\
   verifiers have to establish (using other means) that the potential\
   collisions cannot actually occur; for example, the Certificate Policy\
   Statements (CPSs) of the CAs involved may make it clear that no such\
   name collisions can occur.\
\
\
\
\
Francis & Pinkas            Standards Track                     [Page 6]\
\
RFC 4476                 AC Policies Extension                  May 2006\
\
\
   Implementers MUST ensure that following validation of an AC, only\
   attributes that the issuer is trusted to issue are used in\
   authorization decisions.  Other attributes, which MAY be present,\
   MUST be ignored.  AC verifiers SHALL support means of being provided\
   with this information.  The AA controls PKC extension (see [RFC3281])\
   is one possibility, but it is optional to implement.  Configuration\
   information is a likely alternative means, while out-of-band means is\
   another.  This becomes very important if an AC verification\
   application trusts more than one AC issuer.\
\
4.  IANA Considerations\
\
   The AC policies extension is identified by an object identifier\
   (OID).  The OID for the AC policies extension defined in this\
   document was assigned from an arc delegated by the IANA to the PKIX\
   Working Group.\
\
   No further action by the IANA is necessary for this document.\
\
5.  References\
\
5.1.  Normative References\
\
   [X.660|ISO9834-1] ITU-T Recommendation X.660 (1992) | ISO/IEC 9834-1:\
                     1993, Information technology - Open Systems\
                     Interconnection Procedures for the operation of OSI\
                     Registration Authorities: General procedures.\
\
   [RFC2119]         Bradner, S., "Key words for use in RFCs to Indicate\
                     Requirement Levels", BCP 14, RFC 2119, March 1997.\
\
   [RFC3280]         Housley, R., Polk, W., Ford, W., and D. Solo,\
                     "Internet X.509 Public Key Infrastructure\
                     Certificate and Certificate Revocation List (CRL)\
                     Profile", RFC 3280, April 2002.\
\
   [RFC3281]         Farrell, S. and R. Housley, "An Internet Attribute\
                     Certificate Profile for Authorization", RFC 3281,\
                     April 2002.\
\
   [ASN1]            X.680 - X.693 | ISO/IEC 8824: 1-4 Abstract Syntax\
                     Notation One (ASN.1).\
\
\
\
\
\
\
\
\
\
Francis & Pinkas            Standards Track                     [Page 7]\
\
RFC 4476                 AC Policies Extension                  May 2006\
\
\
5.2.  Informative Reference\
\
   [X.509]           ITU-T Recommendation X.509 (2000): Information\
                     Technology Open Systems Interconnections - The\
                     Directory:  Public-key and Attribute Frameworks,\
                     March 2000.\
\
\
\
\
\
\
\
\
\
\
\
\
\
\
\
\
\
\
\
\
\
\
\
\
\
\
\
\
\
\
\
\
\
\
\
\
\
\
\
\
\
\
\
\
\
Francis & Pinkas            Standards Track                     [Page 8]\
\
RFC 4476                 AC Policies Extension                  May 2006\
\
\
Appendix A.  ASN.1 Definitions\
\
   This appendix is normative.\
\
ASN.1 Module\
\
AcPolicies { iso(1) identified-organization(3) dod(6)\
     internet(1) security(5) mechanisms(5) pkix(7) id-mod(0)\
     id-mod-ac-policies(26) }\
\
DEFINITIONS IMPLICIT TAGS ::=\
\
BEGIN\
\
-- EXPORTS ALL --\
\
IMPORTS\
\
-- Imports from RFC 3280 [RFC3280], Appendix A\
\
       UserNotice\
          FROM PKIX1Implicit88 { iso(1) identified-organization(3)\
          dod(6) internet(1) security(5) mechanisms(5) pkix(7)\
          id-mod(0) 19 }\
\
       id-pkix, id-pe\
          FROM PKIX1Explicit88 { iso(1) identified-organization(3)\
          dod(6) internet(1) security(5) mechanisms(5) pkix(7)\
          id-mod(0) 18 };\
\
-- Locally defined OIDs\
\
    -- policyQualifierIds for Internet policy qualifiers\
\
   id-qt                    OBJECT IDENTIFIER ::=  { id-pkix 2 }\
   id-qt-acps               OBJECT IDENTIFIER ::=  { id-qt 4 }\
   id-qt-acunotice          OBJECT IDENTIFIER ::=  { id-qt 5 }\
\
-- Attributes\
\
   id-pe-acPolicies         OBJECT IDENTIFIER ::= { id-pe 15 }\
\
   AcPoliciesSyntax ::=     SEQUENCE SIZE (1..MAX) OF PolicyInformation\
\
   PolicyInformation ::=    SEQUENCE {\
      policyIdentifier         AcPolicyId,\
      policyQualifiers         SEQUENCE SIZE (1..MAX) OF\
                               PolicyQualifierInfo OPTIONAL }\
\
\
\
Francis & Pinkas            Standards Track                     [Page 9]\
\
RFC 4476                 AC Policies Extension                  May 2006\
\
\
   AcPolicyId ::=           OBJECT IDENTIFIER\
\
   PolicyQualifierInfo ::=  SEQUENCE {\
      policyQualifierId        PolicyQualifierId,\
      qualifier                ANY DEFINED BY policyQualifierId }\
\
   PolicyQualifierId ::=\
      OBJECT IDENTIFIER               ( id-qt-acps | id-qt-acunotice )\
   -- ACPS pointer qualifier\
\
   ACPSuri ::=         IA5String\
   -- ACP statement user notice qualifier\
\
   ACUserNotice ::=    UserNotice\
   -- UserNotice is defined in [RFC3280]\
\
END\
\
Authors' Addresses\
\
   Christopher S. Francis\
   Raytheon\
   1501 72nd Street North, MS 25\
   St. Petersburg, Florida  33764\
\
   EMail: Chris_S_Francis@Raytheon.com\
\
\
   Denis Pinkas\
   Bull\
   Rue Jean Jaures\
   78340 Les Clayes-sous-Bois\
   FRANCE\
\
   EMail: Denis.Pinkas@bull.net\
\
\
\
\
\
\
\
\
\
\
\
\
\
\
\
\
Francis & Pinkas            Standards Track                    [Page 10]\
\
RFC 4476                 AC Policies Extension                  May 2006\
\
\
Full Copyright Statement\
\
   Copyright (C) The Internet Society (2006).\
\
   This document is subject to the rights, licenses and restrictions\
   contained in BCP 78, and except as set forth therein, the authors\
   retain all their rights.\
\
   This document and the information contained herein are provided on an\
   "AS IS" basis and THE CONTRIBUTOR, THE ORGANIZATION HE/SHE REPRESENTS\
   OR IS SPONSORED BY (IF ANY), THE INTERNET SOCIETY AND THE INTERNET\
   ENGINEERING TASK FORCE DISCLAIM ALL WARRANTIES, EXPRESS OR IMPLIED,\
   INCLUDING BUT NOT LIMITED TO ANY WARRANTY THAT THE USE OF THE\
   INFORMATION HEREIN WILL NOT INFRINGE ANY RIGHTS OR ANY IMPLIED\
   WARRANTIES OF MERCHANTABILITY OR FITNESS FOR A PARTICULAR PURPOSE.\
\
Intellectual Property\
\
   The IETF takes no position regarding the validity or scope of any\
   Intellectual Property Rights or other rights that might be claimed to\
   pertain to the implementation or use of the technology described in\
   this document or the extent to which any license under such rights\
   might or might not be available; nor does it represent that it has\
   made any independent effort to identify any such rights.  Information\
   on the procedures with respect to rights in RFC documents can be\
   found in BCP 78 and BCP 79.\
\
   Copies of IPR disclosures made to the IETF Secretariat and any\
   assurances of licenses to be made available, or the result of an\
   attempt made to obtain a general license or permission for the use of\
   such proprietary rights by implementers or users of this\
   specification can be obtained from the IETF on-line IPR repository at\
   http://www.ietf.org/ipr.\
\
   The IETF invites any interested party to bring to its attention any\
   copyrights, patents or patent applications, or other proprietary\
   rights that may cover technology that may be required to implement\
   this standard.  Please address the information to the IETF at\
   ietf-ipr@ietf.org.\
\
Acknowledgement\
\
   Funding for the RFC Editor function is provided by the IETF\
   Administrative Support Activity (IASA).\
\
\
\
\
\
\
\
Francis & Pinkas            Standards Track                    [Page 11]\
\

doc 18
  field 0
    name titolo
    type string
    value rfc4470.txt
  field 1
    name contenuto
    type string
    value \
\
\
\
\
\
Network Working Group                                          S. Weiler\
Request for Comments: 4470                                  SPARTA, Inc.\
Updates: 4035, 4034                                             J. Ihren\
Category: Standards Track                                  Autonomica AB\
                                                              April 2006\
\
\
       Minimally Covering NSEC Records and DNSSEC On-line Signing\
\
\
Status of This Memo\
\
   This document specifies an Internet standards track protocol for the\
   Internet community, and requests discussion and suggestions for\
   improvements.  Please refer to the current edition of the "Internet\
   Official Protocol Standards" (STD 1) for the standardization state\
   and status of this protocol.  Distribution of this memo is unlimited.\
\
Copyright Notice\
\
   Copyright (C) The Internet Society (2006).\
\
Abstract\
\
   This document describes how to construct DNSSEC NSEC resource records\
   that cover a smaller range of names than called for by RFC 4034.  By\
   generating and signing these records on demand, authoritative name\
   servers can effectively stop the disclosure of zone contents\
   otherwise made possible by walking the chain of NSEC records in a\
   signed zone.\
\
Table of Contents\
\
   1. Introduction ....................................................1\
   2. Applicability of This Technique .................................2\
   3. Minimally Covering NSEC Records .................................2\
   4. Better Epsilon Functions ........................................4\
   5. Security Considerations .........................................5\
   6. Acknowledgements ................................................6\
   7. Normative References ............................................6\
\
1.  Introduction\
\
   With DNSSEC [1], an NSEC record lists the next instantiated name in\
   its zone, proving that no names exist in the "span" between the\
   NSEC's owner name and the name in the "next name" field.  In this\
   document, an NSEC record is said to "cover" the names between its\
   owner name and next name.\
\
\
\
Weiler & Ihren              Standards Track                     [Page 1]\
\
RFC 4470                      NSEC Epsilon                    April 2006\
\
\
   Through repeated queries that return NSEC records, it is possible to\
   retrieve all of the names in the zone, a process commonly called\
   "walking" the zone.  Some zone owners have policies forbidding zone\
   transfers by arbitrary clients; this side effect of the NSEC\
   architecture subverts those policies.\
\
   This document presents a way to prevent zone walking by constructing\
   NSEC records that cover fewer names.  These records can make zone\
   walking take approximately as many queries as simply asking for all\
   possible names in a zone, making zone walking impractical.  Some of\
   these records must be created and signed on demand, which requires\
   on-line private keys.  Anyone contemplating use of this technique is\
   strongly encouraged to review the discussion of the risks of on-line\
   signing in Section 5.\
\
1.2.  Keywords\
\
   The keywords "MUST", "MUST NOT", "REQUIRED", "SHALL", "SHALL NOT",\
   "SHOULD", "SHOULD NOT", "RECOMMENDED", "MAY", and "OPTIONAL" in this\
   document are to be interpreted as described in RFC 2119 [4].\
\
2.  Applicability of This Technique\
\
   The technique presented here may be useful to a zone owner that wants\
   to use DNSSEC, is concerned about exposure of its zone contents via\
   zone walking, and is willing to bear the costs of on-line signing.\
\
   As discussed in Section 5, on-line signing has several security\
   risks, including an increased likelihood of private keys being\
   disclosed and an increased risk of denial of service attack.  Anyone\
   contemplating use of this technique is strongly encouraged to review\
   the discussion of the risks of on-line signing in Section 5.\
\
   Furthermore, at the time this document was published, the DNSEXT\
   working group was actively working on a mechanism to prevent zone\
   walking that does not require on-line signing (tentatively called\
   NSEC3).  The new mechanism is likely to expose slightly more\
   information about the zone than this technique (e.g., the number of\
   instantiated names), but it may be preferable to this technique.\
\
3.  Minimally Covering NSEC Records\
\
   This mechanism involves changes to NSEC records for instantiated\
   names, which can still be generated and signed in advance, as well as\
   the on-demand generation and signing of new NSEC records whenever a\
   name must be proven not to exist.\
\
\
\
\
\
Weiler & Ihren              Standards Track                     [Page 2]\
\
RFC 4470                      NSEC Epsilon                    April 2006\
\
\
   In the "next name" field of instantiated names' NSEC records, rather\
   than list the next instantiated name in the zone, list any name that\
   falls lexically after the NSEC's owner name and before the next\
   instantiated name in the zone, according to the ordering function in\
   RFC 4034 [2] Section 6.1.  This relaxes the requirement in Section\
   4.1.1 of RFC 4034 that the "next name" field contains the next owner\
   name in the zone.  This change is expected to be fully compatible\
   with all existing DNSSEC validators.  These NSEC records are returned\
   whenever proving something specifically about the owner name (e.g.,\
   that no resource records of a given type appear at that name).\
\
   Whenever an NSEC record is needed to prove the non-existence of a\
   name, a new NSEC record is dynamically produced and signed.  The new\
   NSEC record has an owner name lexically before the QNAME but\
   lexically following any existing name and a "next name" lexically\
   following the QNAME but before any existing name.\
\
   The generated NSEC record's type bitmap MUST have the RRSIG and NSEC\
   bits set and SHOULD NOT have any other bits set.  This relaxes the\
   requirement in Section 2.3 of RFC4035 that NSEC RRs not appear at\
   names that did not exist before the zone was signed.\
\
   The functions to generate the lexically following and proceeding\
   names need not be perfect or consistent, but the generated NSEC\
   records must not cover any existing names.  Furthermore, this\
   technique works best when the generated NSEC records cover as few\
   names as possible.  In this document, the functions that generate the\
   nearby names are called "epsilon" functions, a reference to the\
   mathematical convention of using the greek letter epsilon to\
   represent small deviations.\
\
   An NSEC record denying the existence of a wildcard may be generated\
   in the same way.  Since the NSEC record covering a non-existent\
   wildcard is likely to be used in response to many queries,\
   authoritative name servers using the techniques described here may\
   want to pregenerate or cache that record and its corresponding RRSIG.\
\
   For example, a query for an A record at the non-instantiated name\
   example.com might produce the following two NSEC records, the first\
   denying the existence of the name example.com and the second denying\
   the existence of a wildcard:\
\
          exampld.com 3600 IN NSEC example-.com ( RRSIG NSEC )\
\
          \\).com 3600 IN NSEC +.com ( RRSIG NSEC )\
\
\
\
\
\
\
Weiler & Ihren              Standards Track                     [Page 3]\
\
RFC 4470                      NSEC Epsilon                    April 2006\
\
\
   Before answering a query with these records, an authoritative server\
   must test for the existence of names between these endpoints.  If the\
   generated NSEC would cover existing names (e.g., exampldd.com or\
   *bizarre.example.com), a better epsilon function may be used or the\
   covered name closest to the QNAME could be used as the NSEC owner\
   name or next name, as appropriate.  If an existing name is used as\
   the NSEC owner name, that name's real NSEC record MUST be returned.\
   Using the same example, assuming an exampldd.com delegation exists,\
   this record might be returned from the parent:\
\
          exampldd.com 3600 IN NSEC example-.com ( NS DS RRSIG NSEC )\
\
   Like every authoritative record in the zone, each generated NSEC\
   record MUST have corresponding RRSIGs generated using each algorithm\
   (but not necessarily each DNSKEY) in the zone's DNSKEY RRset, as\
   described in RFC 4035 [3] Section 2.2.  To minimize the number of\
   signatures that must be generated, a zone may wish to limit the\
   number of algorithms in its DNSKEY RRset.\
\
4.  Better Epsilon Functions\
\
   Section 6.1 of RFC 4034 defines a strict ordering of DNS names.\
   Working backward from that definition, it should be possible to\
   define epsilon functions that generate the immediately following and\
   preceding names, respectively.  This document does not define such\
   functions.  Instead, this section presents functions that come\
   reasonably close to the perfect ones.  As described above, an\
   authoritative server should still ensure than no generated NSEC\
   covers any existing name.\
\
   To increment a name, add a leading label with a single null (zero-\
   value) octet.\
\
   To decrement a name, decrement the last character of the leftmost\
   label, then fill that label to a length of 63 octets with octets of\
   value 255.  To decrement a null (zero-value) octet, remove the octet\
   -- if an empty label is left, remove the label.  Defining this\
   function numerically: fill the leftmost label to its maximum length\
   with zeros (numeric, not ASCII zeros) and subtract one.\
\
   In response to a query for the non-existent name foo.example.com,\
   these functions produce NSEC records of the following:\
\
\
\
\
\
\
\
\
\
Weiler & Ihren              Standards Track                     [Page 4]\
\
RFC 4470                      NSEC Epsilon                    April 2006\
\
\
     fon\\255\\255\\255\\255\\255\\255\\255\\255\\255\\255\\255\\255\\255\\255\
     \\255\\255\\255\\255\\255\\255\\255\\255\\255\\255\\255\\255\\255\\255\\255\
     \\255\\255\\255\\255\\255\\255\\255\\255\\255\\255\\255\\255\\255\\255\\255\
     \\255\\255\\255\\255\\255\\255\\255\\255\\255\\255\\255\\255\\255\\255\\255\
     \\255.example.com 3600 IN NSEC \\000.foo.example.com ( NSEC RRSIG )\
\
     \\)\\255\\255\\255\\255\\255\\255\\255\\255\\255\\255\\255\\255\\255\\255\\255\
     \\255\\255\\255\\255\\255\\255\\255\\255\\255\\255\\255\\255\\255\\255\\255\
     \\255\\255\\255\\255\\255\\255\\255\\255\\255\\255\\255\\255\\255\\255\\255\
     \\255\\255\\255\\255\\255\\255\\255\\255\\255\\255\\255\\255\\255\\255\\255\
     \\255\\255.example.com 3600 IN NSEC \\000.*.example.com ( NSEC RRSIG )\
\
   The first of these NSEC RRs proves that no exact match for\
   foo.example.com exists, and the second proves that there is no\
   wildcard in example.com.\
\
   Both of these functions are imperfect: they do not take into account\
   constraints on number of labels in a name nor total length of a name.\
   As noted in the previous section, though, this technique does not\
   depend on the use of perfect epsilon functions: it is sufficient to\
   test whether any instantiated names fall into the span covered by the\
   generated NSEC and, if so, substitute those instantiated owner names\
   for the NSEC owner name or next name, as appropriate.\
\
5.  Security Considerations\
\
   This approach requires on-demand generation of RRSIG records.  This\
   creates several new vulnerabilities.\
\
   First, on-demand signing requires that a zone's authoritative servers\
   have access to its private keys.  Storing private keys on well-known\
   Internet-accessible servers may make them more vulnerable to\
   unintended disclosure.\
\
   Second, since generation of digital signatures tends to be\
   computationally demanding, the requirement for on-demand signing\
   makes authoritative servers vulnerable to a denial of service attack.\
\
   Last, if the epsilon functions are predictable, on-demand signing may\
   enable a chosen-plaintext attack on a zone's private keys.  Zones\
   using this approach should attempt to use cryptographic algorithms\
   that are resistant to chosen-plaintext attacks.  It is worth noting\
   that although DNSSEC has a "mandatory to implement" algorithm, that\
   is a requirement on resolvers and validators -- there is no\
   requirement that a zone be signed with any given algorithm.\
\
   The success of using minimally covering NSEC records to prevent zone\
   walking depends greatly on the quality of the epsilon functions\
\
\
\
Weiler & Ihren              Standards Track                     [Page 5]\
\
RFC 4470                      NSEC Epsilon                    April 2006\
\
\
   chosen.  An increment function that chooses a name obviously derived\
   from the next instantiated name may be easily reverse engineered,\
   destroying the value of this technique.  An increment function that\
   always returns a name close to the next instantiated name is likewise\
   a poor choice.  Good choices of epsilon functions are the ones that\
   produce the immediately following and preceding names, respectively,\
   though zone administrators may wish to use less perfect functions\
   that return more human-friendly names than the functions described in\
   Section 4 above.\
\
   Another obvious but misguided concern is the danger from synthesized\
   NSEC records being replayed.  It is possible for an attacker to\
   replay an old but still validly signed NSEC record after a new name\
   has been added in the span covered by that NSEC, incorrectly proving\
   that there is no record at that name.  This danger exists with DNSSEC\
   as defined in [3].  The techniques described here actually decrease\
   the danger, since the span covered by any NSEC record is smaller than\
   before.  Choosing better epsilon functions will further reduce this\
   danger.\
\
6.  Acknowledgements\
\
   Many individuals contributed to this design.  They include, in\
   addition to the authors of this document, Olaf Kolkman, Ed Lewis,\
   Peter Koch, Matt Larson, David Blacka, Suzanne Woolf, Jaap Akkerhuis,\
   Jakob Schlyter, Bill Manning, and Joao Damas.\
\
   In addition, the editors would like to thank Ed Lewis, Scott Rose,\
   and David Blacka for their careful review of the document.\
\
7.  Normative References\
\
   [1]  Arends, R., Austein, R., Larson, M., Massey, D., and S. Rose,\
        "DNS Security Introduction and Requirements", RFC 4033, March\
        2005.\
\
   [2]  Arends, R., Austein, R., Larson, M., Massey, D., and S. Rose,\
        "Resource Records for the DNS Security Extensions", RFC 4034,\
        March 2005.\
\
   [3]  Arends, R., Austein, R., Larson, M., Massey, D., and S. Rose,\
        "Protocol Modifications for the DNS Security Extensions", RFC\
        4035, March 2005.\
\
   [4]  Bradner, S., "Key words for use in RFCs to Indicate Requirement\
        Levels", BCP 14, RFC 2119, March 1997.\
\
\
\
\
\
Weiler & Ihren              Standards Track                     [Page 6]\
\
RFC 4470                      NSEC Epsilon                    April 2006\
\
\
Authors' Addresses\
\
   Samuel Weiler\
   SPARTA, Inc.\
   7075 Samuel Morse Drive\
   Columbia, Maryland  21046\
   US\
\
   EMail: weiler@tislabs.com\
\
\
   Johan Ihren\
   Autonomica AB\
   Bellmansgatan 30\
   Stockholm  SE-118 47\
   Sweden\
\
   EMail: johani@autonomica.se\
\
\
\
\
\
\
\
\
\
\
\
\
\
\
\
\
\
\
\
\
\
\
\
\
\
\
\
\
\
\
\
\
\
Weiler & Ihren              Standards Track                     [Page 7]\
\
RFC 4470                      NSEC Epsilon                    April 2006\
\
\
Full Copyright Statement\
\
   Copyright (C) The Internet Society (2006).\
\
   This document is subject to the rights, licenses and restrictions\
   contained in BCP 78, and except as set forth therein, the authors\
   retain all their rights.\
\
   This document and the information contained herein are provided on an\
   "AS IS" basis and THE CONTRIBUTOR, THE ORGANIZATION HE/SHE REPRESENTS\
   OR IS SPONSORED BY (IF ANY), THE INTERNET SOCIETY AND THE INTERNET\
   ENGINEERING TASK FORCE DISCLAIM ALL WARRANTIES, EXPRESS OR IMPLIED,\
   INCLUDING BUT NOT LIMITED TO ANY WARRANTY THAT THE USE OF THE\
   INFORMATION HEREIN WILL NOT INFRINGE ANY RIGHTS OR ANY IMPLIED\
   WARRANTIES OF MERCHANTABILITY OR FITNESS FOR A PARTICULAR PURPOSE.\
\
Intellectual Property\
\
   The IETF takes no position regarding the validity or scope of any\
   Intellectual Property Rights or other rights that might be claimed to\
   pertain to the implementation or use of the technology described in\
   this document or the extent to which any license under such rights\
   might or might not be available; nor does it represent that it has\
   made any independent effort to identify any such rights.  Information\
   on the procedures with respect to rights in RFC documents can be\
   found in BCP 78 and BCP 79.\
\
   Copies of IPR disclosures made to the IETF Secretariat and any\
   assurances of licenses to be made available, or the result of an\
   attempt made to obtain a general license or permission for the use of\
   such proprietary rights by implementers or users of this\
   specification can be obtained from the IETF on-line IPR repository at\
   http://www.ietf.org/ipr.\
\
   The IETF invites any interested party to bring to its attention any\
   copyrights, patents or patent applications, or other proprietary\
   rights that may cover technology that may be required to implement\
   this standard.  Please address the information to the IETF at\
   ietf-ipr@ietf.org.\
\
Acknowledgement\
\
   Funding for the RFC Editor function is provided by the IETF\
   Administrative Support Activity (IASA).\
\
\
\
\
\
\
\
Weiler & Ihren              Standards Track                     [Page 8]\
\

END
checksum 00000000001052926313
cfs entry for: _th.inf
number of fields 2
  name titolo
  number 0
  index options DOCS_AND_FREQS_AND_POSITIONS
  term vectors false
  payloads false
  norms true
  doc values NONE
  doc values gen -1
  attributes 0
  data dimensional count 0
  index dimensional count 0
  dimensional num bytes 0
  vector number of dimensions 0
  vector encoding FLOAT32
  vector similarity EUCLIDEAN
  soft-deletes false
  name contenuto
  number 1
  index options DOCS_AND_FREQS_AND_POSITIONS
  term vectors false
  payloads false
  norms true
  doc values NONE
  doc values gen -1
  attributes 0
  data dimensional count 0
  index dimensional count 0
  dimensional num bytes 0
  vector number of dimensions 0
  vector encoding FLOAT32
  vector similarity EUCLIDEAN
  soft-deletes false
checksum 00000000001012915120
cfs entry for: _th.len
field titolo
  type NUMERIC
  minvalue 2
  pattern 0
0
T
0
T
0
T
0
T
0
T
0
T
0
T
0
T
0
T
0
T
0
T
0
T
0
T
0
T
0
T
0
T
0
T
0
T
0
T
field contenuto
  type NUMERIC
  minvalue 95
  pattern 00
25
T
18
T
13
T
12
T
13
T
09
T
06
T
05
T
02
T
00
T
21
T
19
T
18
T
14
T
12
T
09
T
04
T
03
T
02
T
END
checksum 00000000004075719045
cfs entry for: _th.pst
field contenuto
  term 0
    doc 0
      freq 27
      pos 1260
      pos 1430
      pos 1527
      pos 1551
      pos 1743
      pos 1794
      pos 1968
      pos 1991
      pos 2018
      pos 2053
      pos 2088
      pos 2288
      pos 2946
      pos 5563
      pos 6164
      pos 6502
      pos 9001
      pos 9170
      pos 9355
      pos 12259
      pos 12501
      pos 12531
      pos 12567
      pos 12575
      pos 12602
      pos 12726
      pos 14088
    doc 1
      freq 84
      pos 2450
      pos 2454
      pos 2464
      pos 2474
      pos 2484
      pos 2560
      pos 2600
      pos 3636
      pos 3640
      pos 3650
      pos 3660
      pos 3670
      pos 3781
      pos 3807
      pos 3834
      pos 3998
      pos 4002
      pos 4012
      pos 4022
      pos 4032
      pos 4034
      pos 4035
      pos 4074
      pos 4078
      pos 4088
      pos 4098
      pos 4108
      pos 4110
      pos 4111
      pos 4295
      pos 5064
      pos 5068
      pos 5078
      pos 5088
      pos 5098
      pos 5101
      pos 5233
      pos 5237
      pos 5247
      pos 5257
      pos 5267
      pos 5269
      pos 5340
      pos 5511
      pos 5551
      pos 5695
      pos 5699
      pos 5709
      pos 5719
      pos 5729
      pos 5739
      pos 5740
      pos 5747
      pos 6030
      pos 6034
      pos 6044
      pos 6054
      pos 6064
      pos 6265
      pos 6333
      pos 6536
      pos 6544
      pos 6732
      pos 6826
      pos 6845
      pos 6874
      pos 6910
      pos 7080
      pos 7167
      pos 7227
      pos 7833
      pos 7839
      pos 7845
      pos 7851
      pos 7858
      pos 7863
      pos 7869
      pos 7875
      pos 9422
      pos 9447
      pos 9451
      pos 9453
      pos 9455
      pos 9475
    doc 3
      freq 41
      pos 3631
      pos 3635
      pos 3645
      pos 3655
      pos 3665
      pos 3667
      pos 3668
      pos 3669
      pos 3670
      pos 3686
      pos 3708
      pos 3758
      pos 5073
      pos 5091
      pos 5259
      pos 5688
      pos 5691
      pos 5692
      pos 5693
      pos 5702
      pos 5703
      pos 5704
      pos 5705
      pos 5706
      pos 5707
      pos 5708
      pos 5709
      pos 5712
      pos 5713
      pos 5714
      pos 5715
      pos 5716
      pos 5717
      pos 5718
      pos 5722
      pos 5723
      pos 5724
      pos 5733
      pos 5744
      pos 5755
      pos 5766
    doc 4
      freq 45
      pos 586
      pos 590
      pos 600
      pos 610
      pos 620
      pos 722
      pos 2092
      pos 2096
      pos 2106
      pos 2116
      pos 2126
      pos 2168
      pos 2305
      pos 2758
      pos 2762
      pos 2772
      pos 2782
      pos 2792
      pos 2836
      pos 3003
      pos 3007
      pos 3017
      pos 3027
      pos 3037
      pos 3079
      pos 3151
      pos 3239
      pos 3243
      pos 3253
      pos 3263
      pos 3273
      pos 3315
      pos 3454
      pos 3546
      pos 3550
      pos 3560
      pos 3570
      pos 3580
      pos 3602
      pos 3717
      pos 3721
      pos 3731
      pos 3741
      pos 3751
      pos 3781
    doc 5
      freq 24
      pos 1572
      pos 1576
      pos 1586
      pos 1596
      pos 1606
      pos 1708
      pos 1713
      pos 1794
      pos 1798
      pos 1808
      pos 1818
      pos 1828
      pos 2105
      pos 2127
      pos 2609
      pos 2613
      pos 2623
      pos 2633
      pos 2643
      pos 2674
      pos 2689
      pos 3897
      pos 4054
      pos 4062
    doc 6
      freq 2
      pos 1817
      pos 1818
    doc 8
      freq 2
      pos 368
      pos 1531
    doc 10
      freq 18
      pos 6374
      pos 6392
      pos 6393
      pos 6399
      pos 6402
      pos 6499
      pos 6517
      pos 6518
      pos 6536
      pos 6539
      pos 6674
      pos 6692
      pos 6693
      pos 6699
      pos 6702
      pos 7008
      pos 7154
      pos 7383
    doc 11
      freq 107
      pos 1186
      pos 1533
      pos 1547
      pos 1548
      pos 1554
      pos 2001
      pos 2251
      pos 2265
      pos 2266
      pos 2272
      pos 2403
      pos 2605
      pos 2707
      pos 3169
      pos 3183
      pos 3184
      pos 3190
      pos 3362
      pos 3402
      pos 3416
      pos 3417
      pos 3423
      pos 3555
      pos 3679
      pos 4045
      pos 4059
      pos 4060
      pos 4066
      pos 4158
      pos 4310
      pos 4324
      pos 4325
      pos 4331
      pos 4491
      pos 4505
      pos 4506
      pos 4512
      pos 4684
      pos 4705
      pos 4719
      pos 4720
      pos 4726
      pos 4935
      pos 4945
      pos 5061
      pos 5196
      pos 5210
      pos 5211
      pos 5217
      pos 5353
      pos 5368
      pos 5374
      pos 5501
      pos 5516
      pos 5522
      pos 5661
      pos 5675
      pos 5676
      pos 5682
      pos 5825
      pos 5981
      pos 5995
      pos 5996
      pos 6002
      pos 6205
      pos 6219
      pos 6220
      pos 6226
      pos 6381
      pos 6473
      pos 6636
      pos 6709
      pos 6794
      pos 6895
      pos 6912
      pos 6996
      pos 7133
      pos 7229
      pos 7243
      pos 7244
      pos 7250
      pos 7408
      pos 7539
      pos 7671
      pos 7773
      pos 8073
      pos 8185
      pos 8199
      pos 8200
      pos 8206
      pos 8514
      pos 8528
      pos 8529
      pos 8535
      pos 8630
      pos 8633
      pos 8762
      pos 8852
      pos 8951
      pos 9109
      pos 9123
      pos 9124
      pos 9130
      pos 9286
      pos 9300
      pos 9301
      pos 9307
    doc 17
      freq 3
      pos 2187
      pos 2227
      pos 2252
    skipList 
      level 0
        skipDoc 10
        skipDocFP 25
        impacts 
          impact 
            freq 2
            norm 97
          impact 
            freq 24
            norm 104
          impact 
            freq 41
            norm 107
          impact 
            freq 45
            norm 108
          impact 
            freq 84
            norm 113
        impactsEnd 
  term 0.0
    doc 12
      freq 1
      pos 5344
  term 0.1.0.0.2
    doc 12
      freq 1
      pos 5348
  term 0.2.5
    doc 11
      freq 1
      pos 3851
  term 0.33
    doc 11
      freq 1
      pos 1531
  term 0.5
    doc 12
      freq 1
      pos 3547
  term 0.8
    doc 12
      freq 1
      pos 5346
  term 00
    doc 0
      freq 2
      pos 10706
      pos 10790
    doc 11
      freq 8
      pos 1949
      pos 2363
      pos 2368
      pos 2393
      pos 2398
      pos 2399
      pos 6190
      pos 6191
  term 000
    doc 14
      freq 9
      pos 3249
      pos 3286
      pos 4158
      pos 4196
      pos 4208
      pos 5007
      pos 5023
      pos 5142
      pos 5160
    doc 18
      freq 2
      pos 1455
      pos 1525
  term 0000
    doc 16
      freq 4
      pos 1973
      pos 1988
      pos 2341
      pos 2356
  term 0009
    doc 11
      freq 1
      pos 1480
  term 0068
    doc 11
      freq 1
      pos 1471
  term 01
    doc 11
      freq 1
      pos 6186
  term 01013109300706052b0e03021a300b06
    doc 11
      freq 1
      pos 3893
  term 011c020101307c3070310b3009060355
    doc 11
      freq 1
      pos 3895
  term 01719
    doc 1
      freq 2
      pos 9390
      pos 9568
    doc 3
      freq 2
      pos 4776
      pos 5933
  term 01821
    doc 1
      freq 1
      pos 9320
    doc 3
      freq 1
      pos 4821
  term 02
    doc 10
      freq 3
      pos 6359
      pos 6492
      pos 6644
  term 02015
    doc 13
      freq 1
      pos 7051
  term 02048
    doc 6
      freq 1
      pos 3190
  term 02140
    doc 1
      freq 1
      pos 9196
  term 02dkhr1h3b4biibh
    doc 11
      freq 1
      pos 10475
  term 02q
    doc 11
      freq 2
      pos 10091
      pos 10120
  term 03
    doc 10
      freq 3
      pos 6360
      pos 6493
      pos 6645
  term 030308070208000400050903
    doc 16
      freq 3
      pos 2178
      pos 2206
      pos 2238
  term 030308070208000400050904
    doc 16
      freq 5
      pos 2394
      pos 2397
      pos 2414
      pos 2433
      pos 2450
  term 030308070208000400050907
    doc 16
      freq 7
      pos 1797
      pos 1825
      pos 1842
      pos 2023
      pos 2026
      pos 2058
      pos 2086
  term 030415
    doc 6
      freq 1
      pos 2931
  term 0312
    doc 6
      freq 1
      pos 3194
  term 03550407130853616e204a6f7365310
    doc 11
      freq 1
      pos 3898
  term 0384840201234ksdfak3j2erwedfsasdf
    doc 11
      freq 1
      pos 8488
  term 04
    doc 11
      freq 1
      pos 3844
  term 04061302555331133011060355040813
    doc 11
      freq 1
      pos 3896
  term 05
    doc 16
      freq 2
      pos 1987
      pos 2355
  term 05753
    doc 0
      freq 2
      pos 1115
      pos 17207
  term 05_025
    doc 2
      freq 1
      pos 2769
  term 05_039
    doc 2
      freq 1
      pos 2792
  term 06484
    doc 4
      freq 1
      pos 6053
  term 0686
    doc 14
      freq 1
      pos 5540
  term 0698
    doc 7
      freq 1
      pos 1834
  term 07
    doc 11
      freq 1
      pos 1945
    doc 16
      freq 2
      pos 1972
      pos 2340
  term 07052
    doc 11
      freq 1
      pos 10573
  term 0726
    doc 7
      freq 1
      pos 1840
  term 0727
    doc 7
      freq 1
      pos 1849
  term 0735
    doc 7
      freq 1
      pos 1854
  term 0736
    doc 7
      freq 1
      pos 1861
  term 0749
    doc 7
      freq 1
      pos 1866
  term 0779
    doc 7
      freq 1
      pos 1872
  term 0885
    doc 7
      freq 1
      pos 1878
  term 09
    doc 16
      freq 1
      pos 1523
  term 0927
    doc 7
      freq 1
      pos 1885
  term 092a864886f70d010701318201203082
    doc 11
      freq 1
      pos 3894
  term 0933
    doc 7
      freq 1
      pos 1892
  term 0946
    doc 7
      freq 1
      pos 1898
  term 0977
    doc 7
      freq 1
      pos 1905
  term 0a43616c69666f726e69613111300f06
    doc 11
      freq 1
      pos 3897
  term 0c
    doc 16
      freq 1
      pos 1525
  term 0eg
    doc 10
      freq 1
      pos 12650
  term 0eyyp
    doc 11
      freq 1
      pos 10312
  term 0gditgykkb3iw
    doc 11
      freq 1
      pos 10164
  term 0goiznqp6bhavkvs8kgnverdmmntzskycvynqfynz
    doc 11
      freq 1
      pos 10304
  term 0gvc
    doc 11
      freq 1
      pos 10077
  term 0ha0isnda977644900765
    doc 11
      freq 1
      pos 3382
  term 0ha0isndaksdj
    doc 11
      freq 1
      pos 3529
  term 0ha0isndaksdj2193423r542w35
    doc 11
      freq 1
      pos 4682
  term 0ha0isndaksdj99sdfafnl3lk233412
    doc 11
      freq 1
      pos 3346
  term 0ha0isndaksdjadsfij34n23d
    doc 11
      freq 1
      pos 7869
  term 0ha0isndaksdjweiafasdk3
    doc 11
      freq 1
      pos 4469
  term 0patdvbazevlhooxo933civut2
    doc 11
      freq 1
      pos 9883
  term 0pchbuvv8jnzk5leh9e9uaporn
    doc 11
      freq 1
      pos 10079
  term 0pjancst5aqes
    doc 10
      freq 1
      pos 12507
  term 0pychoxrhzkzf
    doc 11
      freq 1
      pos 10324
  term 0qrrgixsqyfruixesc6zr
    doc 11
      freq 1
      pos 10311
  term 0s1sr2b
    doc 11
      freq 1
      pos 10301
  term 0tipwesy3revsk
    doc 11
      freq 1
      pos 3801
  term 0tmf5wetp5vpp5
    doc 11
      freq 1
      pos 10154
  term 0x00
    doc 0
      freq 1
      pos 3213
    doc 11
      freq 1
      pos 3714
    doc 14
      freq 5
      pos 764
      pos 941
      pos 1455
      pos 2036
      pos 2919
  term 0x000
    doc 8
      freq 2
      pos 682
      pos 714
  term 0x00000000
    doc 8
      freq 1
      pos 1585
  term 0x00000001
    doc 8
      freq 1
      pos 1592
  term 0x00000002
    doc 8
      freq 1
      pos 1597
  term 0x00000004
    doc 8
      freq 1
      pos 1605
  term 0x00000008
    doc 8
      freq 1
      pos 1613
  term 0x00000010
    doc 8
      freq 1
      pos 1622
  term 0x0000002
    doc 1
      freq 1
      pos 7868
  term 0x00000024
    doc 1
      freq 1
      pos 7832
  term 0x00000025
    doc 1
      freq 1
      pos 7838
  term 0x00000026
    doc 1
      freq 1
      pos 7844
  term 0x00000027
    doc 1
      freq 1
      pos 7850
  term 0x00000028
    doc 1
      freq 2
      pos 5311
      pos 7857
  term 0x00000029
    doc 1
      freq 1
      pos 7862
  term 0x0000002b
    doc 1
      freq 1
      pos 7874
  term 0x0001
    doc 1
      freq 1
      pos 5271
    doc 8
      freq 1
      pos 630
  term 0x0002
    doc 8
      freq 1
      pos 637
  term 0x0003
    doc 8
      freq 1
      pos 644
  term 0x0004
    doc 3
      freq 2
      pos 1837
      pos 2108
    doc 8
      freq 1
      pos 650
  term 0x0005
    doc 3
      freq 1
      pos 1924
    doc 8
      freq 1
      pos 655
  term 0x0006
    doc 8
      freq 1
      pos 658
  term 0x0007
    doc 8
      freq 1
      pos 661
  term 0x0008
    doc 8
      freq 1
      pos 664
  term 0x0009
    doc 8
      freq 1
      pos 673
  term 0x000b
    doc 8
      freq 1
      pos 691
  term 0x000c
    doc 8
      freq 1
      pos 696
  term 0x000d
    doc 8
      freq 1
      pos 705
  term 0x000f
    doc 8
      freq 1
      pos 721
  term 0x0010
    doc 8
      freq 1
      pos 727
  term 0x0011
    doc 8
      freq 1
      pos 735
  term 0x0012
    doc 8
      freq 1
      pos 742
  term 0x0013
    doc 8
      freq 1
      pos 750
  term 0x0014
    doc 8
      freq 1
      pos 757
  term 0x0015
    doc 8
      freq 1
      pos 765
  term 0x0016
    doc 8
      freq 1
      pos 770
  term 0x0017
    doc 8
      freq 1
      pos 775
  term 0x0018
    doc 8
      freq 1
      pos 781
  term 0x0019
    doc 8
      freq 1
      pos 786
  term 0x01
    doc 0
      freq 1
      pos 3214
    doc 8
      freq 3
      pos 1012
      pos 1305
      pos 1500
  term 0x02
    doc 8
      freq 1
      pos 1019
  term 0x0200
    doc 1
      freq 1
      pos 5743
  term 0x03
    doc 0
      freq 1
      pos 3211
    doc 8
      freq 1
      pos 1028
  term 0x04
    doc 8
      freq 1
      pos 1038
  term 0x05
    doc 8
      freq 1
      pos 1046
  term 0x06
    doc 3
      freq 1
      pos 2013
    doc 8
      freq 1
      pos 1051
  term 0x07
    doc 8
      freq 1
      pos 1057
  term 0x08
    doc 8
      freq 1
      pos 1065
  term 0x09
    doc 8
      freq 1
      pos 1072
  term 0x096
    doc 1
      freq 3
      pos 5104
      pos 5750
      pos 7780
  term 0x096b
    doc 1
      freq 2
      pos 4040
      pos 7784
  term 0x096c
    doc 1
      freq 2
      pos 4116
      pos 7789
  term 0x0a
    doc 8
      freq 1
      pos 1077
  term 0x0b
    doc 8
      freq 1
      pos 1083
  term 0x0c
    doc 8
      freq 1
      pos 1090
  term 0x1f
    doc 14
      freq 1
      pos 2193
  term 0x2a
    doc 14
      freq 1
      pos 2253
  term 0x4
    doc 3
      freq 1
      pos 3403
  term 0x49
    doc 0
      freq 1
      pos 3212
  term 0x6
    doc 3
      freq 1
      pos 3405
  term 0x7a
    doc 14
      freq 1
      pos 2203
  term 0x80
    doc 1
      freq 4
      pos 2330
      pos 2444
      pos 2487
      pos 7909
  term 0x81
    doc 1
      freq 6
      pos 2333
      pos 2983
      pos 3626
      pos 3674
      pos 4400
      pos 7911
  term 0xcqrupvncl1u6cxs6py576h1erx1sppnkalplspcqyonp4w8r29v
    doc 11
      freq 1
      pos 9894
  term 0xff
    doc 14
      freq 5
      pos 729
      pos 1025
      pos 1677
      pos 2043
      pos 2920
  term 0ylphqjrowjban
    doc 10
      freq 1
      pos 6224
  term 0zop
    doc 11
      freq 1
      pos 10007
  term 1
    doc 0
      freq 125
      pos 64
      pos 141
      pos 184
      pos 192
      pos 513
      pos 602
      pos 648
      pos 1265
      pos 1281
      pos 1598
      pos 1648
      pos 1849
      pos 1878
      pos 1904
      pos 1944
      pos 2040
      pos 2075
      pos 2281
      pos 2290
      pos 2312
      pos 2316
      pos 2467
      pos 2530
      pos 2611
      pos 2663
      pos 2948
      pos 2991
      pos 3026
      pos 3166
      pos 3199
      pos 3210
      pos 3228
      pos 3316
      pos 3322
      pos 3341
      pos 3374
      pos 3396
      pos 3426
      pos 3447
      pos 3483
      pos 3486
      pos 3677
      pos 3714
      pos 4181
      pos 4226
      pos 4511
      pos 4554
      pos 4667
      pos 4711
      pos 4751
      pos 4810
      pos 5362
      pos 5466
      pos 5575
      pos 5723
      pos 5939
      pos 6294
      pos 6335
      pos 6397
      pos 6979
      pos 7019
      pos 7097
      pos 7154
      pos 7221
      pos 7242
      pos 7302
      pos 7799
      pos 7840
      pos 7894
      pos 8341
      pos 8385
      pos 8392
      pos 8844
      pos 8883
      pos 8913
      pos 8963
      pos 8970
      pos 9003
      pos 9091
      pos 9236
      pos 9486
      pos 9498
      pos 9526
      pos 9669
      pos 9683
      pos 9708
      pos 9895
      pos 9937
      pos 9993
      pos 10031
      pos 10073
      pos 10102
      pos 10236
      pos 10628
      pos 10800
      pos 10916
      pos 11037
      pos 11088
      pos 11247
      pos 11350
      pos 11654
      pos 11726
      pos 11765
      pos 11816
      pos 12105
      pos 12126
      pos 12148
      pos 12159
      pos 12296
      pos 12329
      pos 12335
      pos 12645
      pos 12825
      pos 13958
      pos 14376
      pos 14451
      pos 14475
      pos 14511
      pos 14541
      pos 14617
      pos 14641
      pos 14677
      pos 14701
      pos 14725
      pos 15474
    doc 1
      freq 69
      pos 81
      pos 203
      pos 214
      pos 434
      pos 1038
      pos 1045
      pos 1053
      pos 2451
      pos 2455
      pos 2465
      pos 2475
      pos 2485
      pos 2552
      pos 3637
      pos 3641
      pos 3651
      pos 3661
      pos 3671
      pos 3999
      pos 4003
      pos 4013
      pos 4023
      pos 4033
      pos 4075
      pos 4079
      pos 4089
      pos 4099
      pos 4109
      pos 5065
      pos 5069
      pos 5079
      pos 5089
      pos 5099
      pos 5100
      pos 5234
      pos 5238
      pos 5248
      pos 5258
      pos 5268
      pos 5696
      pos 5700
      pos 5710
      pos 5720
      pos 5730
      pos 5746
      pos 6031
      pos 6035
      pos 6045
      pos 6055
      pos 6065
      pos 6315
      pos 6560
      pos 6585
      pos 6600
      pos 6667
      pos 6720
      pos 6819
      pos 6834
      pos 6885
      pos 7465
      pos 7496
      pos 7565
      pos 7599
      pos 7687
      pos 7691
      pos 9424
      pos 9449
      pos 9457
      pos 9473
    doc 2
      freq 5
      pos 115
      pos 171
      pos 194
      pos 203
      pos 3499
    doc 3
      freq 34
      pos 75
      pos 166
      pos 179
      pos 293
      pos 311
      pos 341
      pos 613
      pos 620
      pos 636
      pos 649
      pos 2349
      pos 3632
      pos 3636
      pos 3646
      pos 3656
      pos 3666
      pos 5015
      pos 5056
      pos 5597
      pos 5679
      pos 5694
      pos 5695
      pos 5696
      pos 5697
      pos 5700
      pos 5719
      pos 5725
      pos 5726
      pos 5734
      pos 5735
      pos 5745
      pos 5746
      pos 5756
      pos 5767
    doc 4
      freq 60
      pos 77
      pos 139
      pos 151
      pos 280
      pos 587
      pos 591
      pos 601
      pos 611
      pos 621
      pos 763
      pos 993
      pos 1647
      pos 1677
      pos 2093
      pos 2097
      pos 2107
      pos 2117
      pos 2127
      pos 2166
      pos 2173
      pos 2360
      pos 2684
      pos 2759
      pos 2763
      pos 2773
      pos 2783
      pos 2793
      pos 3004
      pos 3008
      pos 3018
      pos 3028
      pos 3038
      pos 3085
      pos 3179
      pos 3240
      pos 3244
      pos 3254
      pos 3264
      pos 3274
      pos 3320
      pos 3445
      pos 3484
      pos 3547
      pos 3551
      pos 3561
      pos 3571
      pos 3581
      pos 3718
      pos 3722
      pos 3732
      pos 3742
      pos 3752
      pos 4130
      pos 4802
      pos 4913
      pos 4985
      pos 5073
      pos 5104
      pos 5686
      pos 6086
    doc 5
      freq 29
      pos 61
      pos 247
      pos 257
      pos 357
      pos 1207
      pos 1573
      pos 1577
      pos 1587
      pos 1597
      pos 1607
      pos 1715
      pos 1795
      pos 1799
      pos 1809
      pos 1819
      pos 1829
      pos 1905
      pos 2197
      pos 2504
      pos 2610
      pos 2614
      pos 2624
      pos 2634
      pos 2644
      pos 2676
      pos 2696
      pos 3841
      pos 3850
      pos 3899
    doc 6
      freq 13
      pos 286
      pos 297
      pos 1389
      pos 1442
      pos 1450
      pos 1741
      pos 1743
      pos 1849
      pos 1884
      pos 1905
      pos 1931
      pos 2886
      pos 2990
    doc 7
      freq 10
      pos 115
      pos 119
      pos 155
      pos 194
      pos 199
      pos 910
      pos 1479
      pos 1803
      pos 2374
      pos 2912
    doc 8
      freq 7
      pos 108
      pos 184
      pos 193
      pos 503
      pos 834
      pos 1162
      pos 1343
    doc 9
      freq 14
      pos 63
      pos 117
      pos 119
      pos 150
      pos 177
      pos 229
      pos 295
      pos 381
      pos 767
      pos 793
      pos 1007
      pos 1649
      pos 1779
      pos 1784
    doc 10
      freq 17
      pos 66
      pos 171
      pos 181
      pos 372
      pos 402
      pos 424
      pos 2340
      pos 3926
      pos 4802
      pos 4977
      pos 5323
      pos 5331
      pos 5782
      pos 12446
      pos 13090
      pos 13419
      pos 13447
    doc 11
      freq 23
      pos 98
      pos 188
      pos 553
      pos 558
      pos 1152
      pos 1182
      pos 1921
      pos 1978
      pos 3787
      pos 3827
      pos 4765
      pos 4780
      pos 4790
      pos 4931
      pos 4973
      pos 5331
      pos 5334
      pos 6364
      pos 6706
      pos 9867
      pos 10169
      pos 10575
      pos 10603
    doc 12
      freq 14
      pos 148
      pos 236
      pos 468
      pos 507
      pos 2543
      pos 2847
      pos 2864
      pos 3285
      pos 4464
      pos 6200
      pos 7647
      pos 8113
      pos 8126
      pos 8426
    doc 13
      freq 17
      pos 121
      pos 135
      pos 362
      pos 1211
      pos 3634
      pos 3976
      pos 4377
      pos 4746
      pos 5132
      pos 5814
      pos 6058
      pos 6200
      pos 6408
      pos 6548
      pos 6735
      pos 6995
      pos 6996
    doc 14
      freq 14
      pos 121
      pos 214
      pos 282
      pos 432
      pos 696
      pos 911
      pos 1189
      pos 1191
      pos 1232
      pos 1283
      pos 1390
      pos 1567
      pos 2113
      pos 2573
    doc 15
      freq 6
      pos 191
      pos 203
      pos 311
      pos 343
      pos 543
      pos 3898
    doc 16
      freq 21
      pos 62
      pos 166
      pos 174
      pos 186
      pos 256
      pos 670
      pos 714
      pos 1181
      pos 1441
      pos 1460
      pos 1521
      pos 1632
      pos 1715
      pos 1733
      pos 1742
      pos 1806
      pos 1815
      pos 2187
      pos 2196
      pos 2522
      pos 2665
    doc 17
      freq 31
      pos 59
      pos 154
      pos 162
      pos 463
      pos 480
      pos 486
      pos 527
      pos 534
      pos 544
      pos 595
      pos 789
      pos 800
      pos 864
      pos 871
      pos 889
      pos 896
      pos 1140
      pos 2000
      pos 2010
      pos 2098
      pos 2105
      pos 2160
      pos 2167
      pos 2171
      pos 2178
      pos 2211
      pos 2218
      pos 2236
      pos 2243
      pos 2297
      pos 2308
    doc 18
      freq 7
      pos 68
      pos 152
      pos 154
      pos 183
      pos 187
      pos 244
      pos 2059
    skipList 
      level 0
        skipDoc 7
        skipDocFP 15346
        impacts 
          impact 
            freq 10
            norm 100
          impact 
            freq 13
            norm 101
          impact 
            freq 29
            norm 104
          impact 
            freq 34
            norm 107
          impact 
            freq 60
            norm 108
          impact 
            freq 69
            norm 113
          impact 
            freq 125
            norm 120
        impactsEnd 
        skipDoc 15
        skipDocFP 20696
        impacts 
          impact 
            freq 14
            norm 95
          impact 
            freq 17
            norm 109
          impact 
            freq 23
            norm 114
        impactsEnd 
  term 1,32768
    doc 1
      freq 1
      pos 7516
  term 1.0
    doc 16
      freq 2
      pos 2005
      pos 2373
  term 1.1
    doc 2
      freq 3
      pos 118
      pos 396
      pos 3503
    doc 12
      freq 2
      pos 151
      pos 747
    doc 13
      freq 3
      pos 138
      pos 364
      pos 6901
    doc 17
      freq 1
      pos 260
  term 1.2
    doc 2
      freq 3
      pos 122
      pos 724
      pos 3666
    doc 12
      freq 3
      pos 159
      pos 871
      pos 8772
    doc 13
      freq 2
      pos 143
      pos 1023
    doc 18
      freq 1
      pos 380
  term 1.3
    doc 2
      freq 3
      pos 129
      pos 977
      pos 4105
    doc 12
      freq 5
      pos 168
      pos 903
      pos 1081
      pos 3170
      pos 4145
  term 1.4
    doc 2
      freq 3
      pos 134
      pos 1170
      pos 4366
    doc 12
      freq 2
      pos 176
      pos 1142
  term 1.403.806.3366
    doc 11
      freq 1
      pos 10550
  term 1.5
    doc 2
      freq 3
      pos 138
      pos 1367
      pos 4670
  term 1.5.9
    doc 16
      freq 2
      pos 2423
      pos 2462
  term 1.6
    doc 2
      freq 2
      pos 142
      pos 1476
  term 1.7
    doc 2
      freq 2
      pos 146
      pos 1721
  term 1.8
    doc 2
      freq 2
      pos 150
      pos 1851
  term 10
    doc 0
      freq 22
      pos 1394
      pos 1918
      pos 2848
      pos 3129
      pos 6075
      pos 6424
      pos 6462
      pos 6830
      pos 6838
      pos 6932
      pos 6973
      pos 7146
      pos 7650
      pos 8248
      pos 9316
      pos 10793
      pos 11525
      pos 11527
      pos 11589
      pos 11672
      pos 12594
      pos 13588
    doc 1
      freq 4
      pos 260
      pos 399
      pos 3053
      pos 8891
    doc 2
      freq 2
      pos 3201
      pos 3968
    doc 3
      freq 1
      pos 2821
    doc 4
      freq 5
      pos 196
      pos 1726
      pos 2031
      pos 2033
      pos 2962
    doc 5
      freq 4
      pos 297
      pos 1113
      pos 1455
      pos 2733
    doc 6
      freq 1
      pos 3561
    doc 7
      freq 1
      pos 2936
    doc 8
      freq 1
      pos 453
    doc 10
      freq 8
      pos 207
      pos 228
      pos 3784
      pos 5565
      pos 5621
      pos 5939
      pos 12211
      pos 13253
    doc 11
      freq 4
      pos 2289
      pos 2809
      pos 2871
      pos 5169
    doc 12
      freq 9
      pos 309
      pos 317
      pos 325
      pos 334
      pos 432
      pos 1271
      pos 1276
      pos 3383
      pos 6833
    doc 13
      freq 6
      pos 216
      pos 220
      pos 224
      pos 1701
      pos 3299
      pos 6880
    doc 14
      freq 2
      pos 238
      pos 3256
    doc 15
      freq 5
      pos 282
      pos 285
      pos 2414
      pos 3404
      pos 3591
    doc 16
      freq 1
      pos 2511
    doc 17
      freq 1
      pos 2404
    skipList 
      level 0
        skipDoc 7
        skipDocFP 25535
        impacts 
          impact 
            freq 1
            norm 100
          impact 
            freq 4
            norm 104
          impact 
            freq 5
            norm 108
          impact 
            freq 22
            norm 120
        impactsEnd 
        skipDoc 16
        skipDocFP 26323
        impacts 
          impact 
            freq 1
            norm 97
          impact 
            freq 5
            norm 104
          impact 
            freq 6
            norm 109
          impact 
            freq 9
            norm 113
        impactsEnd 
  term 10.0.0.1
    doc 11
      freq 1
      pos 6362
  term 10.1
    doc 10
      freq 2
      pos 234
      pos 6181
  term 10.2
    doc 10
      freq 2
      pos 243
      pos 6806
  term 100
    doc 0
      freq 2
      pos 6782
      pos 16842
    doc 4
      freq 3
      pos 788
      pos 833
      pos 5128
    doc 11
      freq 3
      pos 1185
      pos 4129
      pos 4934
    doc 12
      freq 4
      pos 2842
      pos 2859
      pos 2947
      pos 3095
    doc 13
      freq 4
      pos 5064
      pos 5069
      pos 7014
      pos 7030
  term 1000
    doc 0
      freq 1
      pos 6971
  term 1000000
    doc 11
      freq 1
      pos 1143
  term 10027
    doc 11
      freq 1
      pos 10600
    doc 13
      freq 1
      pos 7071
  term 101
    doc 0
      freq 2
      pos 175
      pos 17100
    doc 4
      freq 3
      pos 791
      pos 834
      pos 5131
  term 102
    doc 0
      freq 2
      pos 179
      pos 17215
    doc 2
      freq 1
      pos 2243
  term 1024
    doc 8
      freq 1
      pos 517
    doc 10
      freq 1
      pos 5536
  term 1025
    doc 1
      freq 1
      pos 9529
    doc 3
      freq 1
      pos 5894
    doc 8
      freq 1
      pos 535
  term 103
    doc 0
      freq 2
      pos 10531
      pos 17546
    doc 2
      freq 1
      pos 2267
  term 1034
    doc 12
      freq 1
      pos 7008
    doc 14
      freq 1
      pos 5373
  term 1035
    doc 14
      freq 1
      pos 5387
  term 1041
    doc 7
      freq 1
      pos 1911
  term 1043
    doc 7
      freq 1
      pos 1917
  term 10460
    doc 3
      freq 1
      pos 4950
  term 1053
    doc 7
      freq 1
      pos 1926
  term 10589
    doc 0
      freq 14
      pos 323
      pos 359
      pos 1139
      pos 1575
      pos 1719
      pos 1740
      pos 1760
      pos 1845
      pos 1900
      pos 1940
      pos 1986
      pos 2015
      pos 16887
      pos 16915
  term 106
    doc 9
      freq 1
      pos 1698
  term 107
    doc 0
      freq 1
      pos 10462
    doc 9
      freq 1
      pos 1715
  term 10700
    doc 3
      freq 1
      pos 4905
  term 1073
    doc 7
      freq 1
      pos 1933
  term 10733
    doc 0
      freq 2
      pos 367
      pos 16919
  term 1079
    doc 7
      freq 1
      pos 1939
  term 109
    doc 0
      freq 1
      pos 10594
  term 1091
    doc 7
      freq 1
      pos 1945
  term 1096
    doc 7
      freq 1
      pos 1951
  term 11
    doc 0
      freq 11
      pos 2094
      pos 2939
      pos 4856
      pos 6129
      pos 7013
      pos 7666
      pos 9366
      pos 10857
      pos 11557
      pos 12626
      pos 13680
    doc 1
      freq 4
      pos 264
      pos 403
      pos 3423
      pos 8971
    doc 2
      freq 3
      pos 2639
      pos 2673
      pos 3442
    doc 3
      freq 5
      pos 237
      pos 241
      pos 246
      pos 253
      pos 3205
    doc 4
      freq 2
      pos 201
      pos 3199
    doc 5
      freq 4
      pos 301
      pos 308
      pos 2345
      pos 3047
    doc 7
      freq 1
      pos 3266
    doc 10
      freq 8
      pos 211
      pos 255
      pos 2462
      pos 4183
      pos 4500
      pos 7390
      pos 10761
      pos 13274
    doc 11
      freq 3
      pos 162
      pos 172
      pos 2541
    doc 12
      freq 3
      pos 436
      pos 3812
      pos 6992
    doc 13
      freq 8
      pos 228
      pos 236
      pos 239
      pos 243
      pos 252
      pos 1835
      pos 3660
      pos 6906
    doc 14
      freq 1
      pos 3540
    doc 15
      freq 1
      pos 3799
    doc 16
      freq 3
      pos 1967
      pos 2335
      pos 2640
    doc 17
      freq 1
      pos 2736
    skipList 
      level 0
        skipDoc 10
        skipDocFP 30133
        impacts 
          impact 
            freq 1
            norm 100
          impact 
            freq 4
            norm 104
          impact 
            freq 5
            norm 107
          impact 
            freq 8
            norm 116
          impact 
            freq 11
            norm 120
        impactsEnd 
  term 11.1
    doc 12
      freq 2
      pos 439
      pos 6994
  term 11.2
    doc 12
      freq 2
      pos 443
      pos 7468
  term 111
    doc 2
      freq 1
      pos 3364
  term 11141343
    doc 11
      freq 2
      pos 4027
      pos 8496
  term 1122
    doc 4
      freq 3
      pos 1359
      pos 5251
      pos 5263
  term 113330
    doc 16
      freq 2
      pos 2421
      pos 2460
  term 1144
    doc 7
      freq 1
      pos 1958
  term 11467
    doc 16
      freq 1
      pos 2404
  term 116
    doc 1
      freq 1
      pos 8966
    doc 3
      freq 1
      pos 4349
    doc 8
      freq 1
      pos 13
  term 11600
    doc 1
      freq 1
      pos 9341
    doc 3
      freq 1
      pos 4844
  term 1167
    doc 11
      freq 1
      pos 10540
  term 118
    doc 12
      freq 1
      pos 9447
    doc 18
      freq 1
      pos 2182
  term 119
    doc 0
      freq 2
      pos 1490
      pos 2459
  term 11916
    doc 16
      freq 1
      pos 2440
  term 1194
    doc 1
      freq 1
      pos 9370
    doc 3
      freq 1
      pos 4860
  term 1195
    doc 0
      freq 5
      pos 340
      pos 1155
      pos 1691
      pos 1862
      pos 16977
    doc 7
      freq 1
      pos 1969
  term 11iwyan92ry
    doc 10
      freq 1
      pos 6890
  term 12
    doc 0
      freq 8
      pos 2326
      pos 2971
      pos 6185
      pos 7079
      pos 7701
      pos 11591
      pos 12667
      pos 13782
    doc 1
      freq 3
      pos 407
      pos 3608
      pos 9181
    doc 2
      freq 2
      pos 164
      pos 3485
    doc 3
      freq 3
      pos 256
      pos 261
      pos 3614
    doc 4
      freq 2
      pos 206
      pos 3435
    doc 5
      freq 3
      pos 312
      pos 318
      pos 3357
    doc 8
      freq 2
      pos 836
      pos 1086
    doc 10
      freq 7
      pos 217
      pos 263
      pos 1490
      pos 4594
      pos 7766
      pos 8040
      pos 13286
    doc 11
      freq 23
      pos 182
      pos 203
      pos 1555
      pos 2273
      pos 2782
      pos 2849
      pos 3191
      pos 3424
      pos 4067
      pos 4332
      pos 4513
      pos 4727
      pos 5218
      pos 5375
      pos 5523
      pos 5683
      pos 6003
      pos 6227
      pos 6913
      pos 7251
      pos 8207
      pos 8536
      pos 9131
    doc 12
      freq 3
      pos 343
      pos 350
      pos 4194
    doc 13
      freq 6
      pos 257
      pos 260
      pos 264
      pos 2789
      pos 3961
      pos 6920
    doc 14
      freq 1
      pos 3838
    doc 15
      freq 4
      pos 289
      pos 292
      pos 296
      pos 4005
    doc 16
      freq 2
      pos 1982
      pos 2680
    skipList 
      level 0
        skipDoc 10
        skipDocFP 33015
        impacts 
          impact 
            freq 2
            norm 97
          impact 
            freq 3
            norm 104
          impact 
            freq 7
            norm 116
          impact 
            freq 8
            norm 120
        impactsEnd 
  term 120
    doc 0
      freq 1
      pos 7155
  term 1200
    doc 0
      freq 1
      pos 2846
  term 120000
    doc 0
      freq 1
      pos 6933
  term 121
    doc 0
      freq 1
      pos 10370
  term 1214
    doc 13
      freq 1
      pos 7065
  term 122
    doc 0
      freq 1
      pos 10704
  term 123
    doc 0
      freq 1
      pos 10788
  term 1234
    doc 7
      freq 2
      pos 687
      pos 1983
  term 1234abcd
    doc 11
      freq 1
      pos 2694
  term 1234ksdfak3j2erwedfsasdf
    doc 11
      freq 1
      pos 4019
  term 1239
    doc 7
      freq 2
      pos 695
      pos 1991
  term 125
    doc 1
      freq 1
      pos 9191
    doc 7
      freq 1
      pos 504
  term 1256
    doc 7
      freq 1
      pos 2000
  term 126
    doc 3
      freq 1
      pos 4919
  term 1269
    doc 7
      freq 1
      pos 2006
  term 127
    doc 0
      freq 1
      pos 2019
    doc 4
      freq 5
      pos 724
      pos 794
      pos 883
      pos 934
      pos 5134
    doc 8
      freq 3
      pos 867
      pos 1193
      pos 1374
  term 127.0.0.1
    doc 11
      freq 3
      pos 3781
      pos 3796
      pos 3812
  term 127.0.0.2
    doc 16
      freq 2
      pos 1956
      pos 2324
  term 1274
    doc 7
      freq 1
      pos 2019
  term 1276
    doc 7
      freq 2
      pos 704
      pos 2028
  term 1277
    doc 7
      freq 1
      pos 2043
  term 128
    doc 0
      freq 3
      pos 3649
      pos 4165
      pos 11007
    doc 4
      freq 5
      pos 731
      pos 805
      pos 1000
      pos 1437
      pos 3600
    doc 8
      freq 3
      pos 886
      pos 1211
      pos 1392
  term 1285
    doc 7
      freq 2
      pos 719
      pos 2056
  term 129
    doc 0
      freq 1
      pos 1695
    doc 4
      freq 3
      pos 811
      pos 1002
      pos 3779
  term 13
    doc 0
      freq 9
      pos 2536
      pos 2653
      pos 3023
      pos 6209
      pos 7148
      pos 7733
      pos 11635
      pos 12720
      pos 13855
    doc 1
      freq 2
      pos 272
      pos 3905
    doc 2
      freq 3
      pos 169
      pos 174
      pos 3868
    doc 3
      freq 2
      pos 265
      pos 4008
    doc 4
      freq 3
      pos 211
      pos 216
      pos 3625
    doc 5
      freq 3
      pos 322
      pos 326
      pos 3658
    doc 8
      freq 1
      pos 845
    doc 10
      freq 11
      pos 223
      pos 227
      pos 267
      pos 4938
      pos 5304
      pos 6358
      pos 6491
      pos 6643
      pos 7466
      pos 8205
      pos 13312
    doc 11
      freq 2
      pos 3050
      pos 8345
    doc 12
      freq 5
      pos 357
      pos 364
      pos 368
      pos 4559
      pos 7006
    doc 13
      freq 5
      pos 267
      pos 273
      pos 277
      pos 284
      pos 4296
    doc 14
      freq 3
      pos 4134
      pos 5371
      pos 5385
    doc 15
      freq 1
      pos 4068
    doc 16
      freq 1
      pos 3011
    skipList 
      level 0
        skipDoc 10
        skipDocFP 36508
        impacts 
          impact 
            freq 1
            norm 97
          impact 
            freq 3
            norm 104
          impact 
            freq 11
            norm 116
        impactsEnd 
  term 13.1
    doc 10
      freq 4
      pos 271
      pos 4263
      pos 8208
      pos 9748
  term 13.2
    doc 10
      freq 3
      pos 278
      pos 3139
      pos 9556
  term 13.3
    doc 10
      freq 3
      pos 284
      pos 4399
      pos 10008
  term 13.4
    doc 10
      freq 4
      pos 293
      pos 4162
      pos 6149
      pos 10363
  term 13.5
    doc 10
      freq 2
      pos 299
      pos 11003
  term 1300
    doc 1
      freq 2
      pos 9257
      pos 9273
    doc 3
      freq 1
      pos 4787
  term 13035551111
    doc 11
      freq 1
      pos 9256
  term 1305
    doc 5
      freq 1
      pos 4298
  term 1314
    doc 7
      freq 2
      pos 725
      pos 2062
  term 1323
    doc 7
      freq 1
      pos 2075
  term 1328
    doc 7
      freq 2
      pos 738
      pos 2082
  term 1332
    doc 7
      freq 1
      pos 2090
  term 134161461246
    doc 11
      freq 1
      pos 4283
  term 135.180.130.133
    doc 11
      freq 1
      pos 6370
  term 1363
    doc 6
      freq 1
      pos 2901
  term 1370
    doc 7
      freq 2
      pos 746
      pos 2099
  term 1372
    doc 7
      freq 1
      pos 2105
  term 1377
    doc 7
      freq 1
      pos 2112
  term 1378
    doc 7
      freq 2
      pos 752
      pos 2122
  term 138
    doc 0
      freq 2
      pos 1249
      pos 15836
    doc 11
      freq 1
      pos 6893
  term 1381
    doc 7
      freq 2
      pos 651
      pos 2130
  term 13818
    doc 6
      freq 1
      pos 2989
  term 1382
    doc 7
      freq 2
      pos 652
      pos 2139
  term 139122385
    doc 11
      freq 1
      pos 1986
  term 1392934
    doc 11
      freq 1
      pos 6175
  term 1397
    doc 7
      freq 2
      pos 760
      pos 2150
  term 13tresathqydninx0ks
    doc 10
      freq 1
      pos 6856
  term 14
    doc 0
      freq 9
      pos 984
      pos 2717
      pos 6256
      pos 7187
      pos 7191
      pos 11686
      pos 12743
      pos 13939
      pos 16955
    doc 1
      freq 3
      pos 277
      pos 282
      pos 4242
    doc 2
      freq 2
      pos 2888
      pos 4252
    doc 3
      freq 4
      pos 269
      pos 274
      pos 4296
      pos 4506
    doc 4
      freq 3
      pos 221
      pos 3797
      pos 5281
    doc 5
      freq 3
      pos 330
      pos 3910
      pos 4136
    doc 8
      freq 1
      pos 1776
    doc 9
      freq 1
      pos 1679
    doc 10
      freq 9
      pos 305
      pos 5398
      pos 7142
      pos 7241
      pos 7355
      pos 7727
      pos 11442
      pos 13130
      pos 13337
    doc 11
      freq 2
      pos 212
      pos 3317
    doc 12
      freq 3
      pos 375
      pos 381
      pos 5010
    doc 13
      freq 3
      pos 288
      pos 4671
      pos 6749
    doc 14
      freq 2
      pos 247
      pos 4220
    doc 15
      freq 1
      pos 4401
    doc 17
      freq 1
      pos 2041
    doc 18
      freq 1
      pos 2140
    skipList 
      level 0
        skipDoc 9
        skipDocFP 39659
        impacts 
          impact 
            freq 1
            norm 95
          impact 
            freq 3
            norm 104
          impact 
            freq 4
            norm 107
          impact 
            freq 9
            norm 120
        impactsEnd 
        skipDoc 18
        skipDocFP 40230
        impacts 
          impact 
            freq 1
            norm 97
          impact 
            freq 2
            norm 107
          impact 
            freq 3
            norm 109
          impact 
            freq 9
            norm 116
        impactsEnd 
  term 14.1
    doc 2
      freq 1
      pos 709
    doc 10
      freq 2
      pos 309
      pos 11478
  term 14.2
    doc 10
      freq 2
      pos 314
      pos 11548
  term 14.3
    doc 10
      freq 2
      pos 322
      pos 11636
  term 14.4
    doc 10
      freq 2
      pos 330
      pos 11731
  term 14.5
    doc 10
      freq 2
      pos 337
      pos 11843
  term 14.6
    doc 10
      freq 2
      pos 345
      pos 11926
  term 14.7
    doc 10
      freq 3
      pos 350
      pos 5473
      pos 12004
  term 1403
    doc 7
      freq 1
      pos 278
  term 1413
    doc 7
      freq 1
      pos 2165
  term 141334
    doc 11
      freq 1
      pos 3375
  term 1414
    doc 1
      freq 2
      pos 9385
      pos 9563
    doc 3
      freq 2
      pos 4771
      pos 5928
    doc 7
      freq 2
      pos 775
      pos 2169
  term 1415
    doc 7
      freq 2
      pos 779
      pos 2184
  term 1418
    doc 7
      freq 2
      pos 785
      pos 2190
  term 1419
    doc 7
      freq 2
      pos 790
      pos 2195
  term 142
    doc 0
      freq 1
      pos 1697
  term 1420
    doc 7
      freq 1
      pos 2200
  term 1421
    doc 7
      freq 2
      pos 795
      pos 2205
  term 1422
    doc 7
      freq 2
      pos 810
      pos 2220
  term 1423
    doc 7
      freq 2
      pos 824
      pos 2234
  term 1424
    doc 7
      freq 2
      pos 838
      pos 2248
  term 14398234
    doc 11
      freq 2
      pos 2381
      pos 8934
  term 146
    doc 9
      freq 1
      pos 1633
  term 1461
    doc 7
      freq 2
      pos 853
      pos 2263
  term 1469
    doc 7
      freq 2
      pos 864
      pos 2274
  term 147
    doc 10
      freq 2
      pos 6372
      pos 6672
  term 1471
    doc 7
      freq 2
      pos 653
      pos 2284
  term 1472
    doc 7
      freq 2
      pos 654
      pos 2302
  term 1473
    doc 7
      freq 2
      pos 655
      pos 2319
  term 1474
    doc 7
      freq 2
      pos 874
      pos 2338
  term 1478
    doc 7
      freq 2
      pos 893
      pos 2357
  term 1479
    doc 7
      freq 2
      pos 902
      pos 2366
  term 1492
    doc 0
      freq 3
      pos 2854
      pos 2937
      pos 4802
  term 149209342
    doc 11
      freq 1
      pos 5961
  term 1493
    doc 2
      freq 1
      pos 2913
  term 1494
    doc 7
      freq 2
      pos 912
      pos 2376
  term 1496
    doc 7
      freq 2
      pos 924
      pos 2388
  term 14issahvqgnfw4qk
    doc 10
      freq 1
      pos 6894
  term 14tkworacexy0guubkosbqrbntmnqncqp8
    doc 11
      freq 1
      pos 10387
  term 15
    doc 0
      freq 4
      pos 2703
      pos 2896
      pos 12761
      pos 14067
    doc 1
      freq 3
      pos 286
      pos 2505
      pos 4636
    doc 2
      freq 1
      pos 4660
    doc 3
      freq 3
      pos 278
      pos 282
      pos 4557
    doc 4
      freq 3
      pos 225
      pos 233
      pos 4087
    doc 5
      freq 2
      pos 333
      pos 4110
    doc 7
      freq 1
      pos 540
    doc 8
      freq 1
      pos 497
    doc 10
      freq 3
      pos 3778
      pos 5763
      pos 13362
    doc 11
      freq 3
      pos 2865
      pos 3440
      pos 3841
    doc 12
      freq 2
      pos 388
      pos 5419
    doc 13
      freq 3
      pos 291
      pos 295
      pos 5016
    doc 14
      freq 1
      pos 4285
    doc 17
      freq 2
      pos 545
      pos 2293
    skipList 
      level 0
        skipDoc 8
        skipDocFP 43946
        impacts 
          impact 
            freq 1
            norm 97
          impact 
            freq 2
            norm 104
          impact 
            freq 3
            norm 107
          impact 
            freq 4
            norm 120
        impactsEnd 
  term 150
    doc 11
      freq 8
      pos 1478
      pos 2249
      pos 3167
      pos 3400
      pos 5659
      pos 5979
      pos 6203
      pos 9103
  term 1500
    doc 12
      freq 1
      pos 9431
  term 1501
    doc 17
      freq 1
      pos 2371
  term 1502
    doc 7
      freq 2
      pos 958
      pos 2402
  term 1510
    doc 7
      freq 1
      pos 2411
  term 1512
    doc 7
      freq 2
      pos 967
      pos 2419
  term 1513
    doc 7
      freq 2
      pos 973
      pos 2425
  term 1517
    doc 7
      freq 1
      pos 2436
  term 1518
    doc 7
      freq 2
      pos 633
      pos 2449
  term 1519
    doc 7
      freq 2
      pos 635
      pos 2459
  term 152
    doc 11
      freq 3
      pos 4304
      pos 5194
      pos 7227
  term 15205
    doc 1
      freq 2
      pos 9262
      pos 9278
    doc 3
      freq 1
      pos 4792
  term 1525
    doc 7
      freq 2
      pos 984
      pos 2472
  term 154
    doc 11
      freq 3
      pos 4035
      pos 8176
      pos 8504
  term 1552
    doc 7
      freq 2
      pos 994
      pos 2482
  term 1553
    doc 7
      freq 2
      pos 1004
      pos 2491
  term 1570
    doc 7
      freq 1
      pos 2500
  term 1572
    doc 7
      freq 1
      pos 2505
  term 15802
    doc 2
      freq 1
      pos 2524
  term 1582
    doc 7
      freq 2
      pos 656
      pos 2510
  term 1584
    doc 7
      freq 2
      pos 673
      pos 2519
  term 159
    doc 11
      freq 2
      pos 5351
      pos 5499
  term 15932
    doc 11
      freq 1
      pos 8341
  term 1598
    doc 7
      freq 2
      pos 657
      pos 2525
  term 15a06659716292e8da2aa8d8350a68c
    doc 11
      freq 1
      pos 3906
  term 16
    doc 0
      freq 6
      pos 2034
      pos 2081
      pos 3084
      pos 11908
      pos 12205
      pos 14196
    doc 1
      freq 3
      pos 292
      pos 299
      pos 5016
    doc 2
      freq 5
      pos 179
      pos 2716
      pos 2765
      pos 2788
      pos 5021
    doc 3
      freq 5
      pos 2021
      pos 3696
      pos 3719
      pos 3749
      pos 4738
    doc 4
      freq 3
      pos 237
      pos 1260
      pos 4497
    doc 5
      freq 6
      pos 336
      pos 340
      pos 344
      pos 1719
      pos 2711
      pos 4346
    doc 7
      freq 1
      pos 618
    doc 9
      freq 1
      pos 1300
    doc 10
      freq 4
      pos 233
      pos 6053
      pos 12164
      pos 13379
    doc 11
      freq 4
      pos 221
      pos 228
      pos 3685
      pos 6189
    doc 12
      freq 3
      pos 395
      pos 5855
      pos 7067
    doc 13
      freq 3
      pos 300
      pos 304
      pos 5378
    doc 14
      freq 1
      pos 4407
    doc 16
      freq 4
      pos 1970
      pos 1985
      pos 2338
      pos 2353
    skipList 
      level 0
        skipDoc 9
        skipDocFP 46765
        impacts 
          impact 
            freq 1
            norm 95
          impact 
            freq 6
            norm 104
        impactsEnd 
  term 16.4
    doc 10
      freq 1
      pos 2419
  term 16.6
    doc 10
      freq 1
      pos 9231
  term 160
    doc 5
      freq 3
      pos 1304
      pos 1330
      pos 1926
  term 16000
    doc 0
      freq 4
      pos 1632
      pos 2855
      pos 12532
      pos 12576
  term 1602
    doc 7
      freq 1
      pos 163
  term 16066
    doc 1
      freq 1
      pos 9586
  term 1618
    doc 7
      freq 1
      pos 2542
  term 1628
    doc 7
      freq 1
      pos 2547
  term 163
    doc 0
      freq 1
      pos 10374
  term 1633
    doc 6
      freq 1
      pos 2983
  term 164
    doc 0
      freq 1
      pos 10377
    doc 10
      freq 1
      pos 13345
  term 1648
    doc 7
      freq 2
      pos 1013
      pos 2553
  term 16505552222
    doc 11
      freq 1
      pos 9269
  term 1663
    doc 7
      freq 1
      pos 2561
  term 1666
    doc 7
      freq 2
      pos 1021
      pos 2566
  term 16777215
    doc 0
      freq 1
      pos 1795
  term 1692
    doc 7
      freq 2
      pos 1032
      pos 2577
  term 1696
    doc 7
      freq 2
      pos 1038
      pos 2583
  term 1697
    doc 7
      freq 1
      pos 2592
  term 17
    doc 0
      freq 3
      pos 3245
      pos 4957
      pos 14245
    doc 1
      freq 2
      pos 304
      pos 5295
    doc 2
      freq 2
      pos 2760
      pos 5417
    doc 3
      freq 2
      pos 286
      pos 4831
    doc 4
      freq 3
      pos 241
      pos 252
      pos 4883
    doc 5
      freq 1
      pos 4431
    doc 10
      freq 2
      pos 242
      pos 6271
    doc 11
      freq 2
      pos 233
      pos 3881
    doc 12
      freq 3
      pos 400
      pos 407
      pos 6245
    doc 13
      freq 2
      pos 308
      pos 5728
    doc 14
      freq 2
      pos 4501
      pos 5529
    skipList 
      level 0
        skipDoc 11
        skipDocFP 49192
        impacts 
          impact 
            freq 1
            norm 104
          impact 
            freq 2
            norm 107
          impact 
            freq 3
            norm 108
        impactsEnd 
  term 170
    doc 4
      freq 1
      pos 6063
    doc 6
      freq 1
      pos 3185
    doc 10
      freq 1
      pos 13433
  term 17005551008
    doc 10
      freq 2
      pos 7449
      pos 7509
  term 1706
    doc 4
      freq 1
      pos 6071
  term 1714
    doc 16
      freq 1
      pos 2662
  term 1731
    doc 7
      freq 1
      pos 2600
  term 1734
    doc 7
      freq 1
      pos 2605
  term 1738
    doc 7
      freq 1
      pos 2610
  term 1740
    doc 7
      freq 1
      pos 2616
  term 1742
    doc 7
      freq 2
      pos 1047
      pos 2624
  term 1747
    doc 7
      freq 2
      pos 1054
      pos 2631
  term 1749
    doc 7
      freq 2
      pos 1068
      pos 2642
  term 175
    doc 10
      freq 1
      pos 6580
  term 1752
    doc 7
      freq 1
      pos 2652
  term 1755
    doc 7
      freq 2
      pos 659
      pos 2662
  term 1763
    doc 7
      freq 2
      pos 1078
      pos 2671
  term 1764
    doc 7
      freq 2
      pos 1087
      pos 2680
  term 1767
    doc 7
      freq 1
      pos 2689
  term 1793
    doc 7
      freq 1
      pos 2696
  term 18
    doc 0
      freq 3
      pos 3401
      pos 3456
      pos 14359
    doc 1
      freq 3
      pos 310
      pos 5687
      pos 9176
    doc 2
      freq 2
      pos 5822
      pos 6307
    doc 3
      freq 1
      pos 4935
    doc 4
      freq 2
      pos 258
      pos 5154
    doc 5
      freq 1
      pos 4762
    doc 8
      freq 1
      pos 1757
    doc 10
      freq 1
      pos 6524
    doc 11
      freq 2
      pos 238
      pos 3982
    doc 12
      freq 4
      pos 412
      pos 419
      pos 428
      pos 6638
    doc 13
      freq 2
      pos 314
      pos 6007
    doc 14
      freq 1
      pos 4583
    doc 17
      freq 1
      pos 2253
    skipList 
      level 0
        skipDoc 10
        skipDocFP 51184
        impacts 
          impact 
            freq 1
            norm 97
          impact 
            freq 2
            norm 108
          impact 
            freq 3
            norm 113
        impactsEnd 
  term 18.3
    doc 11
      freq 1
      pos 3256
  term 1800
    doc 10
      freq 1
      pos 13409
  term 1808
    doc 7
      freq 1
      pos 2704
  term 1812
    doc 7
      freq 1
      pos 2710
    doc 11
      freq 1
      pos 5055
  term 1828
    doc 7
      freq 2
      pos 1096
      pos 2718
  term 1829
    doc 7
      freq 2
      pos 1136
      pos 2725
  term 1831
    doc 7
      freq 1
      pos 2732
  term 1833
    doc 7
      freq 1
      pos 2742
  term 1835
    doc 7
      freq 2
      pos 1103
      pos 2751
  term 1847
    doc 7
      freq 1
      pos 2758
  term 1848
    doc 7
      freq 2
      pos 1110
      pos 2769
  term 1865
    doc 14
      freq 1
      pos 5521
  term 188
    doc 6
      freq 1
      pos 2091
  term 1893884
    doc 11
      freq 1
      pos 5639
  term 19
    doc 0
      freq 2
      pos 3668
      pos 7372
    doc 1
      freq 2
      pos 316
      pos 6022
    doc 2
      freq 1
      pos 6215
    doc 3
      freq 1
      pos 5000
    doc 4
      freq 4
      pos 261
      pos 265
      pos 269
      pos 5399
    doc 10
      freq 4
      pos 6779
      pos 7143
      pos 7242
      pos 7356
    doc 11
      freq 2
      pos 243
      pos 4168
    doc 12
      freq 3
      pos 431
      pos 435
      pos 6983
    doc 13
      freq 3
      pos 317
      pos 323
      pos 6329
    doc 14
      freq 2
      pos 255
      pos 4961
    doc 17
      freq 1
      pos 2228
    skipList 
      level 0
        skipDoc 12
        skipDocFP 52940
        impacts 
          impact 
            freq 1
            norm 107
          impact 
            freq 4
            norm 108
        impactsEnd 
  term 19102
    doc 12
      freq 1
      pos 9436
  term 1913
    doc 7
      freq 2
      pos 1116
      pos 2775
  term 1914
    doc 7
      freq 2
      pos 1124
      pos 2783
  term 1918181833n
    doc 11
      freq 1
      pos 1461
  term 192.0.2.1
    doc 11
      freq 18
      pos 1475
      pos 2258
      pos 2263
      pos 3176
      pos 3181
      pos 3551
      pos 5485
      pos 5508
      pos 5513
      pos 5668
      pos 5673
      pos 5988
      pos 5993
      pos 6902
      pos 6906
      pos 7120
      pos 8147
      pos 8932
    doc 12
      freq 3
      pos 2840
      pos 2857
      pos 8420
  term 192.0.2.103
    doc 11
      freq 1
      pos 7508
  term 192.0.2.105
    doc 11
      freq 2
      pos 4137
      pos 6975
  term 192.0.2.125
    doc 11
      freq 1
      pos 3357
  term 192.0.2.129
    doc 11
      freq 1
      pos 5035
  term 192.0.2.15
    doc 11
      freq 10
      pos 3383
      pos 3391
      pos 3409
      pos 3414
      pos 4297
      pos 4317
      pos 4322
      pos 5203
      pos 5208
      pos 9098
  term 192.0.2.155
    doc 11
      freq 2
      pos 4498
      pos 4503
  term 192.0.2.198
    doc 11
      freq 6
      pos 4013
      pos 4052
      pos 4057
      pos 8475
      pos 8521
      pos 8526
  term 192.0.2.2
    doc 11
      freq 2
      pos 1486
      pos 8154
  term 192.0.2.21
    doc 11
      freq 1
      pos 7664
  term 192.0.2.25
    doc 11
      freq 3
      pos 8135
      pos 8192
      pos 8197
  term 192.0.2.253
    doc 11
      freq 1
      pos 8063
  term 192.0.2.3
    doc 11
      freq 1
      pos 1540
  term 192.0.2.4
    doc 10
      freq 3
      pos 6982
      pos 7119
      pos 7332
    doc 11
      freq 1
      pos 1545
  term 192.0.2.5
    doc 11
      freq 11
      pos 3138
      pos 5332
      pos 5340
      pos 5360
      pos 5365
      pos 6212
      pos 6217
      pos 9116
      pos 9121
      pos 9293
      pos 9298
  term 192.0.2.53
    doc 11
      freq 3
      pos 4690
      pos 4712
      pos 4717
  term 192.0.2.59
    doc 11
      freq 1
      pos 5184
  term 192.0.2.95
    doc 11
      freq 3
      pos 7219
      pos 7236
      pos 7241
  term 192.168.255.111
    doc 11
      freq 1
      pos 1519
  term 1928
    doc 7
      freq 1
      pos 2792
  term 1928301774
    doc 10
      freq 5
      pos 6343
      pos 6628
      pos 6999
      pos 7136
      pos 7349
  term 1929
    doc 7
      freq 1
      pos 2798
  term 193942
    doc 11
      freq 1
      pos 7213
  term 1961
    doc 7
      freq 1
      pos 2806
  term 1962
    doc 7
      freq 1
      pos 2816
  term 1964
    doc 7
      freq 1
      pos 2824
  term 1968
    doc 7
      freq 1
      pos 2833
  term 19725552222
    doc 11
      freq 2
      pos 8757
      pos 8847
  term 1973
    doc 7
      freq 1
      pos 2841
  term 1980s
    doc 2
      freq 3
      pos 62
      pos 208
      pos 3517
  term 1981
    doc 4
      freq 2
      pos 5225
      pos 5362
  term 1982
    doc 7
      freq 1
      pos 2847
  term 1984
    doc 7
      freq 2
      pos 743
      pos 2087
  term 1985
    doc 7
      freq 1
      pos 2852
  term 1987
    doc 12
      freq 1
      pos 7010
    doc 14
      freq 2
      pos 5375
      pos 5389
  term 1988
    doc 7
      freq 4
      pos 741
      pos 915
      pos 2085
      pos 2379
    doc 17
      freq 1
      pos 474
  term 1989
    doc 4
      freq 1
      pos 5265
  term 1990
    doc 0
      freq 1
      pos 16979
  term 1990s
    doc 2
      freq 2
      pos 3674
      pos 4841
    doc 7
      freq 1
      pos 1356
  term 1992
    doc 5
      freq 1
      pos 4300
    doc 6
      freq 1
      pos 2903
    doc 17
      freq 1
      pos 2006
  term 1993
    doc 2
      freq 1
      pos 2915
    doc 17
      freq 1
      pos 2011
  term 1994
    doc 0
      freq 2
      pos 1162
      pos 15846
    doc 6
      freq 1
      pos 2985
  term 1995
    doc 1
      freq 1
      pos 9132
    doc 7
      freq 1
      pos 2862
  term 1996
    doc 1
      freq 1
      pos 9146
    doc 2
      freq 4
      pos 2619
      pos 2620
      pos 3774
      pos 4110
    doc 4
      freq 1
      pos 5364
    doc 7
      freq 2
      pos 1817
      pos 2869
    doc 16
      freq 1
      pos 2590
  term 1997
    doc 0
      freq 1
      pos 16959
    doc 1
      freq 1
      pos 8910
    doc 2
      freq 2
      pos 2941
      pos 4265
    doc 3
      freq 1
      pos 4510
    doc 4
      freq 1
      pos 5285
    doc 5
      freq 1
      pos 4140
    doc 6
      freq 3
      pos 2892
      pos 2950
      pos 2965
    doc 7
      freq 1
      pos 2881
    doc 8
      freq 1
      pos 1780
    doc 9
      freq 1
      pos 1683
    doc 10
      freq 1
      pos 13134
    doc 12
      freq 3
      pos 7033
      pos 7048
      pos 7071
    doc 13
      freq 1
      pos 6753
    doc 14
      freq 1
      pos 5404
    doc 15
      freq 1
      pos 3908
    doc 16
      freq 1
      pos 2544
    doc 17
      freq 2
      pos 484
      pos 2045
    doc 18
      freq 1
      pos 2144
    skipList 
      level 0
        skipDoc 7
        skipDocFP 58033
        impacts 
          impact 
            freq 1
            norm 100
          impact 
            freq 3
            norm 101
        impactsEnd 
        skipDoc 16
        skipDocFP 58383
        impacts 
          impact 
            freq 1
            norm 95
          impact 
            freq 3
            norm 113
        impactsEnd 
  term 1998
    doc 0
      freq 1
      pos 16940
    doc 1
      freq 1
      pos 9180
    doc 2
      freq 7
      pos 2553
      pos 2554
      pos 2575
      pos 2968
      pos 2984
      pos 3426
      pos 4300
    doc 3
      freq 2
      pos 4470
      pos 4491
    doc 4
      freq 4
      pos 5191
      pos 5211
      pos 5249
      pos 5381
    doc 5
      freq 2
      pos 4161
      pos 4314
    doc 8
      freq 2
      pos 1745
      pos 1761
    doc 12
      freq 1
      pos 7085
    doc 13
      freq 1
      pos 6770
    doc 15
      freq 1
      pos 3922
    skipList 
      level 0
        skipDoc 12
        skipDocFP 59246
        impacts 
          impact 
            freq 2
            norm 97
          impact 
            freq 7
            norm 108
        impactsEnd 
  term 1999
    doc 0
      freq 3
      pos 17059
      pos 17077
      pos 17095
    doc 2
      freq 1
      pos 3015
    doc 10
      freq 1
      pos 13273
    doc 12
      freq 1
      pos 7097
    doc 13
      freq 1
      pos 6905
  term 19r98
    doc 11
      freq 1
      pos 10400
  term 1_unusual.ur
    doc 11
      freq 2
      pos 1912
      pos 1956
  term 1bj
    doc 15
      freq 1
      pos 4030
  term 1csurjjf9lvff
    doc 11
      freq 1
      pos 10098
  term 1cwtsztng3iv
    doc 10
      freq 2
      pos 7277
      pos 7367
  term 1dzp
    doc 11
      freq 1
      pos 10282
  term 1fv
    doc 11
      freq 1
      pos 10283
  term 1gh
    doc 10
      freq 1
      pos 12674
  term 1i74vpo89mxqurny
    doc 10
      freq 1
      pos 12804
  term 1lgdvr9deczcj10yuq3mremdmxhy2
    doc 10
      freq 1
      pos 6283
  term 1nmurlxv
    doc 10
      freq 2
      pos 7278
      pos 7368
  term 1nt
    doc 1
      freq 1
      pos 9552
    doc 3
      freq 1
      pos 5917
  term 1ntnrp2s
    doc 11
      freq 1
      pos 10192
  term 1pfm5
    doc 11
      freq 1
      pos 10284
  term 1st
    doc 3
      freq 1
      pos 2799
  term 1uyj2ebckgustsif6cyjzibvslpcyioy6a7poqr
    doc 11
      freq 1
      pos 9929
  term 1x7
    doc 11
      freq 1
      pos 10547
  term 2
    doc 0
      freq 76
      pos 147
      pos 148
      pos 150
      pos 299
      pos 485
      pos 537
      pos 597
      pos 651
      pos 1029
      pos 1248
      pos 1270
      pos 1295
      pos 1600
      pos 1650
      pos 1851
      pos 1880
      pos 1907
      pos 1946
      pos 2377
      pos 2381
      pos 2522
      pos 2950
      pos 3007
      pos 3131
      pos 3313
      pos 3768
      pos 4280
      pos 4580
      pos 4804
      pos 5428
      pos 5620
      pos 5725
      pos 5941
      pos 6426
      pos 6781
      pos 6886
      pos 7189
      pos 7374
      pos 7768
      pos 7842
      pos 7925
      pos 8394
      pos 8410
      pos 8972
      pos 8994
      pos 9005
      pos 9093
      pos 9431
      pos 9552
      pos 9749
      pos 10151
      pos 10238
      pos 10802
      pos 11145
      pos 11352
      pos 11656
      pos 11840
      pos 12065
      pos 12191
      pos 12355
      pos 12647
      pos 12917
      pos 13962
      pos 14381
      pos 14453
      pos 14477
      pos 14513
      pos 14619
      pos 14643
      pos 14679
      pos 14703
      pos 14727
      pos 14759
      pos 15542
      pos 15835
      pos 17052
    doc 1
      freq 53
      pos 107
      pos 129
      pos 187
      pos 217
      pos 238
      pos 426
      pos 450
      pos 1041
      pos 1047
      pos 1106
      pos 1134
      pos 1154
      pos 1198
      pos 1466
      pos 1478
      pos 1729
      pos 1984
      pos 2452
      pos 2456
      pos 2466
      pos 2476
      pos 3638
      pos 3642
      pos 3652
      pos 3662
      pos 4000
      pos 4004
      pos 4014
      pos 4024
      pos 4076
      pos 4080
      pos 4090
      pos 4100
      pos 5066
      pos 5070
      pos 5080
      pos 5090
      pos 5235
      pos 5239
      pos 5249
      pos 5259
      pos 5697
      pos 5701
      pos 5711
      pos 5721
      pos 6032
      pos 6036
      pos 6046
      pos 6056
      pos 6141
      pos 7702
      pos 7955
      pos 8057
    doc 2
      freq 7
      pos 117
      pos 121
      pos 154
      pos 176
      pos 623
      pos 1940
      pos 4835
    doc 3
      freq 35
      pos 182
      pos 298
      pos 321
      pos 331
      pos 616
      pos 622
      pos 745
      pos 790
      pos 843
      pos 1220
      pos 1229
      pos 2436
      pos 2875
      pos 2900
      pos 3633
      pos 3637
      pos 3647
      pos 3657
      pos 4270
      pos 5062
      pos 5212
      pos 5256
      pos 5277
      pos 5657
      pos 5680
      pos 5698
      pos 5710
      pos 5727
      pos 5728
      pos 5736
      pos 5737
      pos 5747
      pos 5757
      pos 5768
      pos 5798
    doc 4
      freq 48
      pos 153
      pos 154
      pos 388
      pos 420
      pos 471
      pos 588
      pos 592
      pos 602
      pos 612
      pos 769
      pos 1653
      pos 1696
      pos 1702
      pos 2094
      pos 2098
      pos 2108
      pos 2118
      pos 2179
      pos 2387
      pos 2760
      pos 2764
      pos 2774
      pos 2784
      pos 2832
      pos 3005
      pos 3009
      pos 3019
      pos 3029
      pos 3241
      pos 3245
      pos 3255
      pos 3265
      pos 3326
      pos 3447
      pos 3548
      pos 3552
      pos 3562
      pos 3572
      pos 3719
      pos 3723
      pos 3733
      pos 3743
      pos 4178
      pos 4397
      pos 4845
      pos 5077
      pos 5085
      pos 5573
    doc 5
      freq 23
      pos 260
      pos 350
      pos 1044
      pos 1264
      pos 1574
      pos 1578
      pos 1588
      pos 1598
      pos 1796
      pos 1800
      pos 1810
      pos 1820
      pos 1920
      pos 2246
      pos 2530
      pos 2611
      pos 2615
      pos 2625
      pos 2635
      pos 2683
      pos 2706
      pos 3873
      pos 3880
    doc 6
      freq 5
      pos 739
      pos 909
      pos 1064
      pos 1882
      pos 2992
    doc 7
      freq 8
      pos 120
      pos 124
      pos 132
      pos 300
      pos 586
      pos 1514
      pos 2740
      pos 2749
    doc 8
      freq 9
      pos 110
      pos 111
      pos 115
      pos 119
      pos 124
      pos 302
      pos 471
      pos 1171
      pos 1352
    doc 9
      freq 7
      pos 120
      pos 123
      pos 372
      pos 382
      pos 592
      pos 1619
      pos 1665
    doc 10
      freq 10
      pos 184
      pos 395
      pos 669
      pos 702
      pos 2521
      pos 4152
      pos 5778
      pos 12646
      pos 13116
      pos 13440
    doc 11
      freq 10
      pos 101
      pos 491
      pos 768
      pos 3998
      pos 4001
      pos 4763
      pos 4778
      pos 4788
      pos 4971
      pos 8753
    doc 12
      freq 10
      pos 184
      pos 476
      pos 498
      pos 1229
      pos 2554
      pos 3329
      pos 4473
      pos 6209
      pos 8142
      pos 8643
    doc 13
      freq 15
      pos 149
      pos 351
      pos 429
      pos 1180
      pos 1898
      pos 3673
      pos 4021
      pos 4854
      pos 5189
      pos 5831
      pos 6080
      pos 6214
      pos 6416
      pos 6633
      pos 6757
    doc 14
      freq 15
      pos 123
      pos 124
      pos 464
      pos 557
      pos 567
      pos 743
      pos 948
      pos 1117
      pos 1228
      pos 1339
      pos 1434
      pos 1610
      pos 1861
      pos 2128
      pos 2706
    doc 15
      freq 5
      pos 206
      pos 302
      pos 399
      pos 559
      pos 3909
    doc 16
      freq 14
      pos 267
      pos 507
      pos 532
      pos 838
      pos 847
      pos 1353
      pos 1562
      pos 1636
      pos 1717
      pos 1736
      pos 1863
      pos 2067
      pos 2076
      pos 2535
    doc 17
      freq 6
      pos 294
      pos 513
      pos 841
      pos 881
      pos 906
      pos 2268
    doc 18
      freq 7
      pos 155
      pos 160
      pos 166
      pos 411
      pos 620
      pos 675
      pos 2080
    skipList 
      level 0
        skipDoc 7
        skipDocFP 61339
        impacts 
          impact 
            freq 8
            norm 100
          impact 
            freq 23
            norm 104
          impact 
            freq 35
            norm 107
          impact 
            freq 48
            norm 108
          impact 
            freq 53
            norm 113
          impact 
            freq 76
            norm 120
        impactsEnd 
        skipDoc 15
        skipDocFP 65331
        impacts 
          impact 
            freq 7
            norm 95
          impact 
            freq 9
            norm 97
          impact 
            freq 15
            norm 107
        impactsEnd 
  term 2.0
    doc 10
      freq 10
      pos 6325
      pos 6328
      pos 6610
      pos 6613
      pos 6977
      pos 6980
      pos 7114
      pos 7117
      pos 7327
      pos 7330
    doc 11
      freq 139
      pos 583
      pos 1455
      pos 1484
      pos 1511
      pos 1517
      pos 1930
      pos 1934
      pos 2200
      pos 2224
      pos 2360
      pos 2385
      pos 2558
      pos 2577
      pos 2678
      pos 2701
      pos 2798
      pos 2921
      pos 2927
      pos 2933
      pos 2939
      pos 2945
      pos 2951
      pos 2957
      pos 2963
      pos 2969
      pos 2975
      pos 2981
      pos 2987
      pos 2993
      pos 2999
      pos 3005
      pos 3011
      pos 3017
      pos 3023
      pos 3029
      pos 3035
      pos 3041
      pos 3061
      pos 3067
      pos 3073
      pos 3079
      pos 3085
      pos 3091
      pos 3097
      pos 3103
      pos 3109
      pos 3115
      pos 3121
      pos 3127
      pos 3134
      pos 3332
      pos 3355
      pos 3367
      pos 3389
      pos 3514
      pos 3549
      pos 3617
      pos 3640
      pos 3648
      pos 3656
      pos 3664
      pos 3672
      pos 3775
      pos 3779
      pos 3996
      pos 4011
      pos 4128
      pos 4135
      pos 4275
      pos 4295
      pos 4451
      pos 4475
      pos 4667
      pos 4688
      pos 4904
      pos 4907
      pos 5021
      pos 5028
      pos 5155
      pos 5182
      pos 5316
      pos 5338
      pos 5457
      pos 5483
      pos 5622
      pos 5643
      pos 5789
      pos 5795
      pos 5935
      pos 5965
      pos 6157
      pos 6179
      pos 6347
      pos 6368
      pos 6438
      pos 6441
      pos 6600
      pos 6603
      pos 6767
      pos 6788
      pos 6859
      pos 6883
      pos 6964
      pos 6973
      pos 7104
      pos 7118
      pos 7211
      pos 7217
      pos 7380
      pos 7400
      pos 7511
      pos 7531
      pos 7639
      pos 7662
      pos 7737
      pos 7764
      pos 7850
      pos 7875
      pos 8041
      pos 8061
      pos 8126
      pos 8133
      pos 8319
      pos 8322
      pos 8468
      pos 8473
      pos 8480
      pos 8605
      pos 8622
      pos 8728
      pos 8731
      pos 8818
      pos 8821
      pos 8917
      pos 8938
      pos 9068
      pos 9096
      pos 9248
      pos 9251
  term 2.1
    doc 2
      freq 1
      pos 4986
    doc 4
      freq 4
      pos 160
      pos 529
      pos 5992
      pos 6000
    doc 11
      freq 2
      pos 105
      pos 874
    doc 12
      freq 2
      pos 192
      pos 1252
    doc 13
      freq 2
      pos 152
      pos 1212
    doc 17
      freq 1
      pos 773
  term 2.1.1
    doc 17
      freq 1
      pos 1007
  term 2.2
    doc 2
      freq 1
      pos 5629
    doc 4
      freq 2
      pos 165
      pos 1057
    doc 11
      freq 2
      pos 110
      pos 994
    doc 12
      freq 2
      pos 197
      pos 1322
    doc 17
      freq 1
      pos 1257
    doc 18
      freq 1
      pos 1177
  term 2.3
    doc 2
      freq 1
      pos 6038
    doc 4
      freq 3
      pos 171
      pos 1252
      pos 5768
    doc 11
      freq 2
      pos 116
      pos 1087
    doc 12
      freq 2
      pos 201
      pos 1396
    doc 18
      freq 1
      pos 822
  term 2.4
    doc 4
      freq 13
      pos 176
      pos 958
      pos 1343
      pos 1413
      pos 2751
      pos 2997
      pos 3233
      pos 3536
      pos 4377
      pos 4404
      pos 5566
      pos 5732
      pos 5748
    doc 12
      freq 2
      pos 205
      pos 1499
  term 2.4.2
    doc 1
      freq 1
      pos 2083
  term 2.5
    doc 1
      freq 1
      pos 2085
  term 2.9
    doc 1
      freq 1
      pos 8632
  term 20
    doc 0
      freq 6
      pos 1431
      pos 3803
      pos 3948
      pos 3979
      pos 7465
      pos 10499
    doc 1
      freq 3
      pos 320
      pos 331
      pos 6363
    doc 2
      freq 1
      pos 6329
    doc 3
      freq 3
      pos 291
      pos 296
      pos 5196
    doc 4
      freq 2
      pos 272
      pos 5529
    doc 9
      freq 1
      pos 727
    doc 10
      freq 2
      pos 254
      pos 6965
    doc 11
      freq 12
      pos 247
      pos 253
      pos 260
      pos 2820
      pos 2859
      pos 2880
      pos 2891
      pos 2898
      pos 2905
      pos 2913
      pos 4131
      pos 4408
    doc 12
      freq 3
      pos 438
      pos 442
      pos 7230
    doc 13
      freq 3
      pos 330
      pos 334
      pos 6651
    doc 14
      freq 3
      pos 263
      pos 5189
      pos 5538
    doc 16
      freq 7
      pos 1720
      pos 1785
      pos 1804
      pos 1813
      pos 2065
      pos 2074
      pos 2100
    skipList 
      level 0
        skipDoc 11
        skipDocFP 71541
        impacts 
          impact 
            freq 1
            norm 95
          impact 
            freq 3
            norm 107
          impact 
            freq 12
            norm 114
        impactsEnd 
  term 200
    doc 4
      freq 3
      pos 817
      pos 835
      pos 5142
    doc 11
      freq 6
      pos 462
      pos 3920
      pos 3997
      pos 8370
      pos 8469
      pos 10539
    doc 12
      freq 2
      pos 3002
      pos 3115
    doc 17
      freq 1
      pos 1214
  term 2000
    doc 0
      freq 2
      pos 16993
      pos 17146
    doc 2
      freq 6
      pos 3036
      pos 3045
      pos 3064
      pos 3088
      pos 3102
      pos 4020
    doc 3
      freq 2
      pos 4408
      pos 4695
    doc 4
      freq 1
      pos 5327
    doc 7
      freq 2
      pos 480
      pos 1620
    doc 10
      freq 1
      pos 13283
    doc 12
      freq 4
      pos 7122
      pos 7487
      pos 7510
      pos 7526
    doc 13
      freq 1
      pos 6785
    doc 14
      freq 1
      pos 5427
    doc 17
      freq 2
      pos 2129
      pos 2143
    skipList 
      level 0
        skipDoc 13
        skipDocFP 73078
        impacts 
          impact 
            freq 2
            norm 100
          impact 
            freq 6
            norm 108
        impactsEnd 
  term 2001
    doc 1
      freq 2
      pos 8928
      pos 8952
    doc 2
      freq 6
      pos 2496
      pos 2498
      pos 3117
      pos 4745
      pos 4991
      pos 5036
    doc 3
      freq 2
      pos 4400
      pos 4626
    doc 5
      freq 2
      pos 4282
      pos 4286
    doc 8
      freq 1
      pos 2077
    doc 11
      freq 1
      pos 9628
    doc 12
      freq 8
      pos 2845
      pos 2862
      pos 5330
      pos 7108
      pos 7140
      pos 7157
      pos 7170
      pos 8424
    doc 13
      freq 1
      pos 6935
    doc 15
      freq 1
      pos 3936
    doc 16
      freq 1
      pos 2568
    skipList 
      level 0
        skipDoc 13
        skipDocFP 73881
        impacts 
          impact 
            freq 1
            norm 97
          impact 
            freq 2
            norm 104
          impact 
            freq 6
            norm 108
          impact 
            freq 8
            norm 113
        impactsEnd 
  term 2002
    doc 0
      freq 5
      pos 16916
      pos 17013
      pos 17038
      pos 17171
      pos 17194
    doc 2
      freq 5
      pos 2360
      pos 2874
      pos 5196
      pos 5338
      pos 5747
    doc 5
      freq 1
      pos 4340
    doc 6
      freq 2
      pos 2918
      pos 3027
    doc 10
      freq 12
      pos 6357
      pos 6490
      pos 6642
      pos 7141
      pos 7240
      pos 7354
      pos 13115
      pos 13150
      pos 13167
      pos 13211
      pos 13252
      pos 13311
    doc 11
      freq 2
      pos 9654
      pos 9673
    doc 12
      freq 3
      pos 1417
      pos 7224
      pos 7258
    doc 13
      freq 2
      pos 6853
      pos 6919
    doc 17
      freq 2
      pos 2072
      pos 2089
    skipList 
      level 0
        skipDoc 13
        skipDocFP 74842
        impacts 
          impact 
            freq 2
            norm 101
          impact 
            freq 5
            norm 108
          impact 
            freq 12
            norm 116
        impactsEnd 
  term 2003
    doc 2
      freq 16
      pos 2381
      pos 2425
      pos 2478
      pos 2653
      pos 2654
      pos 3134
      pos 3157
      pos 3184
      pos 3197
      pos 3226
      pos 3244
      pos 3262
      pos 5487
      pos 5502
      pos 5794
      pos 6008
    doc 4
      freq 1
      pos 5345
    doc 6
      freq 4
      pos 2932
      pos 3007
      pos 3061
      pos 3085
    doc 10
      freq 1
      pos 13225
    doc 12
      freq 3
      pos 7195
      pos 7279
      pos 7297
    doc 15
      freq 1
      pos 3961
    doc 16
      freq 2
      pos 2534
      pos 2558
  term 2004
    doc 2
      freq 18
      pos 379
      pos 835
      pos 1377
      pos 2442
      pos 2501
      pos 2517
      pos 2519
      pos 2692
      pos 3282
      pos 4619
      pos 4929
      pos 5251
      pos 5284
      pos 5319
      pos 5600
      pos 5654
      pos 5701
      pos 5709
    doc 3
      freq 1
      pos 4588
    doc 5
      freq 2
      pos 4181
      pos 4375
    doc 7
      freq 4
      pos 308
      pos 494
      pos 541
      pos 619
    doc 9
      freq 1
      pos 1664
    doc 10
      freq 3
      pos 13183
      pos 13324
      pos 13361
    doc 12
      freq 6
      pos 7313
      pos 7327
      pos 7344
      pos 7543
      pos 7770
      pos 7809
    doc 15
      freq 1
      pos 3977
    doc 16
      freq 4
      pos 1969
      pos 1984
      pos 2337
      pos 2352
    skipList 
      level 0
        skipDoc 15
        skipDocFP 76470
        impacts 
          impact 
            freq 1
            norm 95
          impact 
            freq 4
            norm 100
          impact 
            freq 18
            norm 108
        impactsEnd 
  term 2005
    doc 0
      freq 1
      pos 17127
    doc 1
      freq 1
      pos 9164
    doc 2
      freq 17
      pos 2247
      pos 2271
      pos 2280
      pos 2336
      pos 2349
      pos 2747
      pos 2761
      pos 2784
      pos 2817
      pos 2845
      pos 2889
      pos 3303
      pos 3326
      pos 3350
      pos 3368
      pos 3384
      pos 6308
    doc 3
      freq 10
      pos 4403
      pos 4445
      pos 4451
      pos 4465
      pos 4531
      pos 4641
      pos 4660
      pos 4680
      pos 4712
      pos 4731
    doc 4
      freq 4
      pos 5299
      pos 5392
      pos 5420
      pos 5437
    doc 5
      freq 2
      pos 4209
      pos 4254
    doc 7
      freq 1
      pos 313
    doc 8
      freq 5
      pos 1829
      pos 1844
      pos 1863
      pos 2053
      pos 2098
    doc 9
      freq 3
      pos 1702
      pos 1719
      pos 1761
    doc 10
      freq 2
      pos 13199
      pos 13378
    doc 11
      freq 3
      pos 3843
      pos 9694
      pos 9713
    doc 12
      freq 14
      pos 7367
      pos 7385
      pos 7407
      pos 7422
      pos 7554
      pos 7570
      pos 7588
      pos 7606
      pos 7648
      pos 7654
      pos 7675
      pos 7697
      pos 7725
      pos 7858
    doc 13
      freq 1
      pos 6827
    doc 14
      freq 2
      pos 5450
      pos 5504
    doc 16
      freq 2
      pos 2604
      pos 2620
    doc 18
      freq 3
      pos 2079
      pos 2102
      pos 2125
    skipList 
      level 0
        skipDoc 8
        skipDocFP 77573
        impacts 
          impact 
            freq 5
            norm 97
          impact 
            freq 10
            norm 107
          impact 
            freq 17
            norm 108
        impactsEnd 
        skipDoc 18
        skipDocFP 78374
        impacts 
          impact 
            freq 3
            norm 95
          impact 
            freq 14
            norm 113
        impactsEnd 
  term 2006
    doc 0
      freq 108
      pos 16
      pos 87
      pos 191
      pos 492
      pos 666
      pos 827
      pos 999
      pos 1077
      pos 1208
      pos 1214
      pos 1238
      pos 1406
      pos 1618
      pos 1784
      pos 1925
      pos 2101
      pos 2333
      pos 2543
      pos 2724
      pos 2903
      pos 3091
      pos 3252
      pos 3463
      pos 3675
      pos 3810
      pos 4021
      pos 4206
      pos 4409
      pos 4552
      pos 4709
      pos 4825
      pos 5047
      pos 5241
      pos 5478
      pos 5592
      pos 5774
      pos 5955
      pos 6183
      pos 6348
      pos 6438
      pos 6658
      pos 6912
      pos 7091
      pos 7255
      pos 7356
      pos 7518
      pos 7683
      pos 7822
      pos 7956
      pos 8140
      pos 8335
      pos 8425
      pos 8644
      pos 8832
      pos 8932
      pos 9084
      pos 9249
      pos 9443
      pos 9599
      pos 9743
      pos 9909
      pos 10049
      pos 10175
      pos 10389
      pos 10588
      pos 10814
      pos 11026
      pos 11100
      pos 11308
      pos 11489
      pos 11647
      pos 11778
      pos 11884
      pos 12055
      pos 12182
      pos 12318
      pos 12471
      pos 12643
      pos 12791
      pos 12996
      pos 13187
      pos 13346
      pos 13546
      pos 13740
      pos 13930
      pos 14141
      pos 14328
      pos 14505
      pos 14671
      pos 14809
      pos 14929
      pos 15056
      pos 15183
      pos 15313
      pos 15424
      pos 15495
      pos 15566
      pos 15644
      pos 15728
      pos 15805
      pos 16137
      pos 16326
      pos 16478
      pos 16611
      pos 16849
      pos 17107
      pos 17222
      pos 17231
    doc 1
      freq 37
      pos 34
      pos 104
      pos 210
      pos 433
      pos 841
      pos 1070
      pos 1378
      pos 1871
      pos 2231
      pos 2427
      pos 2701
      pos 3060
      pos 3430
      pos 3615
      pos 3912
      pos 4249
      pos 4643
      pos 5023
      pos 5302
      pos 5694
      pos 6029
      pos 6370
      pos 6765
      pos 7203
      pos 7645
      pos 7895
      pos 8243
      pos 8711
      pos 8970
      pos 9026
      pos 9120
      pos 9230
      pos 9337
      pos 9407
      pos 9502
      pos 9603
      pos 9612
    doc 2
      freq 26
      pos 16
      pos 57
      pos 202
      pos 631
      pos 1081
      pos 1475
      pos 1850
      pos 2223
      pos 2322
      pos 2460
      pos 2704
      pos 2953
      pos 3209
      pos 3409
      pos 3450
      pos 3493
      pos 3876
      pos 4260
      pos 4668
      pos 5029
      pos 5425
      pos 5830
      pos 6223
      pos 6337
      pos 6400
      pos 6409
    doc 3
      freq 31
      pos 29
      pos 98
      pos 175
      pos 340
      pos 587
      pos 767
      pos 1046
      pos 1432
      pos 1785
      pos 2124
      pos 2435
      pos 2830
      pos 3214
      pos 3623
      pos 4017
      pos 4305
      pos 4335
      pos 4353
      pos 4383
      pos 4550
      pos 4566
      pos 4608
      pos 4747
      pos 4840
      pos 4944
      pos 5009
      pos 5205
      pos 5595
      pos 5796
      pos 5952
      pos 5961
    doc 4
      freq 26
      pos 27
      pos 100
      pos 147
      pos 428
      pos 748
      pos 1017
      pos 1374
      pos 1761
      pos 2083
      pos 2320
      pos 2724
      pos 2970
      pos 3207
      pos 3443
      pos 3633
      pos 3805
      pos 4095
      pos 4505
      pos 4891
      pos 5162
      pos 5407
      pos 5537
      pos 5822
      pos 6041
      pos 6107
      pos 6116
    doc 5
      freq 22
      pos 16
      pos 84
      pos 253
      pos 356
      pos 792
      pos 1149
      pos 1480
      pos 1747
      pos 2050
      pos 2361
      pos 2558
      pos 2739
      pos 3053
      pos 3363
      pos 3664
      pos 3916
      pos 4116
      pos 4237
      pos 4352
      pos 4395
      pos 4437
      pos 4446
    doc 6
      freq 12
      pos 18
      pos 60
      pos 296
      pos 749
      pos 1139
      pos 1620
      pos 2035
      pos 2349
      pos 2765
      pos 3042
      pos 3232
      pos 3241
    doc 7
      freq 13
      pos 19
      pos 71
      pos 205
      pos 592
      pos 956
      pos 1306
      pos 1654
      pos 1828
      pos 2182
      pos 2540
      pos 2895
      pos 2942
      pos 2951
    doc 8
      freq 14
      pos 15
      pos 65
      pos 192
      pos 479
      pos 804
      pos 1131
      pos 1445
      pos 1675
      pos 1811
      pos 1936
      pos 2008
      pos 2126
      pos 2159
      pos 2168
    doc 9
      freq 9
      pos 16
      pos 86
      pos 238
      pos 601
      pos 942
      pos 1378
      pos 1733
      pos 1804
      pos 1813
    doc 10
      freq 44
      pos 18
      pos 89
      pos 177
      pos 401
      pos 792
      pos 1255
      pos 1706
      pos 2093
      pos 2519
      pos 2974
      pos 3378
      pos 3790
      pos 4189
      pos 4600
      pos 4944
      pos 5404
      pos 5769
      pos 6059
      pos 6277
      pos 6530
      pos 6785
      pos 6971
      pos 7275
      pos 7605
      pos 8037
      pos 8471
      pos 8991
      pos 9481
      pos 9946
      pos 10336
      pos 10792
      pos 11209
      pos 11547
      pos 11842
      pos 12099
      pos 12390
      pos 12537
      pos 12701
      pos 12836
      pos 13086
      pos 13336
      pos 13402
      pos 13465
      pos 13474
    doc 11
      freq 55
      pos 30
      pos 73
      pos 196
      pos 499
      pos 826
      pos 1052
      pos 1259
      pos 1445
      pos 1579
      pos 1903
      pos 2117
      pos 2297
      pos 2549
      pos 2790
      pos 3058
      pos 3325
      pos 3448
      pos 3693
      pos 3889
      pos 3990
      pos 4176
      pos 4416
      pos 4659
      pos 4897
      pos 5075
      pos 5242
      pos 5399
      pos 5547
      pos 5707
      pos 5839
      pos 6027
      pos 6251
      pos 6487
      pos 6723
      pos 6937
      pos 7147
      pos 7275
      pos 7553
      pos 7787
      pos 8034
      pos 8231
      pos 8463
      pos 8647
      pos 8866
      pos 8965
      pos 9210
      pos 9420
      pos 9727
      pos 9865
      pos 10031
      pos 10221
      pos 10430
      pos 10523
      pos 10626
      pos 10635
    doc 12
      freq 40
      pos 20
      pos 63
      pos 244
      pos 506
      pos 870
      pos 1228
      pos 1565
      pos 1950
      pos 2284
      pos 2655
      pos 3027
      pos 3391
      pos 3820
      pos 4202
      pos 4567
      pos 5018
      pos 5427
      pos 5863
      pos 6253
      pos 6646
      pos 6991
      pos 7238
      pos 7437
      pos 7453
      pos 7467
      pos 7623
      pos 7711
      pos 7741
      pos 7757
      pos 7787
      pos 7823
      pos 7841
      pos 7877
      pos 7891
      pos 8244
      pos 8641
      pos 9053
      pos 9425
      pos 9476
      pos 9485
    doc 13
      freq 26
      pos 30
      pos 72
      pos 131
      pos 361
      pos 765
      pos 1147
      pos 1468
      pos 1827
      pos 2179
      pos 2571
      pos 2942
      pos 3309
      pos 3670
      pos 3971
      pos 4306
      pos 4681
      pos 5026
      pos 5388
      pos 5738
      pos 6017
      pos 6339
      pos 6661
      pos 6879
      pos 6951
      pos 7091
      pos 7100
    doc 14
      freq 26
      pos 15
      pos 67
      pos 223
      pos 566
      pos 850
      pos 1227
      pos 1556
      pos 1877
      pos 2167
      pos 2558
      pos 2912
      pos 3265
      pos 3549
      pos 3847
      pos 4143
      pos 4229
      pos 4294
      pos 4416
      pos 4510
      pos 4592
      pos 4970
      pos 5198
      pos 5464
      pos 5486
      pos 5557
      pos 5566
    doc 15
      freq 17
      pos 24
      pos 71
      pos 199
      pos 310
      pos 640
      pos 1030
      pos 1398
      pos 1758
      pos 2153
      pos 2599
      pos 3011
      pos 3412
      pos 3807
      pos 3999
      pos 4013
      pos 4076
      pos 4085
    doc 16
      freq 16
      pos 15
      pos 85
      pos 173
      pos 539
      pos 914
      pos 1319
      pos 1574
      pos 1693
      pos 1861
      pos 2119
      pos 2256
      pos 2518
      pos 2635
      pos 2647
      pos 2687
      pos 2696
    doc 17
      freq 13
      pos 17
      pos 82
      pos 161
      pos 520
      pos 820
      pos 1058
      pos 1404
      pos 1853
      pos 2118
      pos 2156
      pos 2325
      pos 2411
      pos 2420
    doc 18
      freq 10
      pos 22
      pos 91
      pos 250
      pos 626
      pos 1034
      pos 1389
      pos 1816
      pos 2156
      pos 2199
      pos 2208
    skipList 
      level 0
        skipDoc 7
        skipDocFP 79508
        impacts 
          impact 
            freq 13
            norm 100
          impact 
            freq 22
            norm 104
          impact 
            freq 31
            norm 107
          impact 
            freq 37
            norm 113
          impact 
            freq 108
            norm 120
        impactsEnd 
        skipDoc 15
        skipDocFP 83818
        impacts 
          impact 
            freq 9
            norm 95
          impact 
            freq 14
            norm 97
          impact 
            freq 17
            norm 104
          impact 
            freq 26
            norm 107
          impact 
            freq 40
            norm 113
          impact 
            freq 55
            norm 114
        impactsEnd 
  term 200604040000z
    doc 0
      freq 2
      pos 1074
      pos 1235
  term 201
    doc 4
      freq 3
      pos 820
      pos 837
      pos 5145
  term 2010
    doc 11
      freq 1
      pos 6188
  term 20191
    doc 3
      freq 1
      pos 4910
  term 20193
    doc 1
      freq 1
      pos 9349
    doc 3
      freq 1
      pos 4852
  term 2020
    doc 11
      freq 1
      pos 5791
  term 2026
    doc 7
      freq 4
      pos 160
      pos 1513
      pos 1526
      pos 1815
  term 204
    doc 0
      freq 1
      pos 1699
  term 2045
    doc 16
      freq 1
      pos 2588
  term 206f6
    doc 11
      freq 1
      pos 1069
  term 20hav
    doc 11
      freq 1
      pos 2208
  term 20hkcfeaefxsw6rvcrncp23hxyrxjpm1sc4oprai6xsw126fw2qbdlb4sjonn37r
    doc 10
      freq 1
      pos 12666
  term 20spaces
    doc 11
      freq 1
      pos 2209
  term 20wisrg1j1rnmigbbgnvhsmeejb4gbtzlpzk21whbcg6
    doc 10
      freq 1
      pos 6263
  term 21
    doc 0
      freq 2
      pos 4014
      pos 7495
    doc 1
      freq 2
      pos 343
      pos 6758
    doc 2
      freq 2
      pos 190
      pos 6392
    doc 3
      freq 3
      pos 304
      pos 309
      pos 5586
    doc 4
      freq 2
      pos 279
      pos 5814
    doc 10
      freq 8
      pos 6355
      pos 6488
      pos 6640
      pos 7139
      pos 7238
      pos 7269
      pos 7352
      pos 13439
    doc 11
      freq 2
      pos 265
      pos 4651
    doc 12
      freq 1
      pos 7459
    doc 13
      freq 3
      pos 338
      pos 342
      pos 6941
    doc 14
      freq 5
      pos 267
      pos 270
      pos 273
      pos 277
      pos 5455
    doc 16
      freq 4
      pos 2166
      pos 2185
      pos 2194
      pos 2350
    skipList 
      level 0
        skipDoc 12
        skipDocFP 89878
        impacts 
          impact 
            freq 3
            norm 107
          impact 
            freq 8
            norm 116
        impactsEnd 
  term 21046
    doc 18
      freq 1
      pos 2169
  term 2108
    doc 2
      freq 1
      pos 2939
  term 211
    doc 13
      freq 1
      pos 7001
  term 2119
    doc 0
      freq 2
      pos 986
      pos 16957
    doc 1
      freq 1
      pos 8908
    doc 3
      freq 2
      pos 1261
      pos 4508
    doc 4
      freq 3
      pos 470
      pos 5267
      pos 5283
    doc 5
      freq 2
      pos 1074
      pos 4138
    doc 8
      freq 1
      pos 1778
    doc 9
      freq 2
      pos 371
      pos 1681
    doc 10
      freq 2
      pos 701
      pos 13132
    doc 13
      freq 2
      pos 1210
      pos 6751
    doc 17
      freq 1
      pos 2043
    doc 18
      freq 2
      pos 409
      pos 2142
    skipList 
      level 0
        skipDoc 10
        skipDocFP 91024
        impacts 
          impact 
            freq 2
            norm 95
          impact 
            freq 3
            norm 108
        impactsEnd 
  term 212
    doc 11
      freq 1
      pos 10604
  term 2130706432
    doc 11
      freq 1
      pos 5479
  term 2131
    doc 15
      freq 2
      pos 112
      pos 3906
  term 2136
    doc 12
      freq 1
      pos 7031
  term 2147483647
    doc 0
      freq 2
      pos 12336
      pos 12502
  term 2181
    doc 12
      freq 1
      pos 7046
    doc 14
      freq 1
      pos 5402
  term 2182
    doc 12
      freq 1
      pos 7069
  term 2192
    doc 16
      freq 1
      pos 2542
  term 22
    doc 0
      freq 2
      pos 4199
      pos 7538
    doc 1
      freq 2
      pos 349
      pos 7196
    doc 2
      freq 1
      pos 6723
    doc 3
      freq 2
      pos 319
      pos 5787
    doc 4
      freq 1
      pos 6033
    doc 10
      freq 2
      pos 262
      pos 7599
    doc 11
      freq 2
      pos 273
      pos 4889
    doc 12
      freq 2
      pos 446
      pos 7703
    doc 13
      freq 2
      pos 345
      pos 7081
    doc 14
      freq 2
      pos 281
      pos 5548
    skipList 
      level 0
        skipDoc 12
        skipDocFP 92300
        impacts 
          impact 
            freq 2
            norm 107
        impactsEnd 
  term 22.3
    doc 10
      freq 1
      pos 2626
  term 2205
    doc 6
      freq 1
      pos 2890
  term 2211
    doc 6
      freq 1
      pos 2963
  term 2212
    doc 6
      freq 1
      pos 2948
  term 2229
    doc 11
      freq 2
      pos 4032
      pos 8501
  term 2234
    doc 10
      freq 1
      pos 5099
  term 2234923
    doc 11
      freq 1
      pos 6165
  term 225
    doc 1
      freq 1
      pos 9205
  term 2277
    doc 1
      freq 1
      pos 9178
    doc 8
      freq 1
      pos 1759
  term 2284
    doc 2
      freq 1
      pos 2966
  term 23
    doc 0
      freq 2
      pos 4402
      pos 7565
    doc 1
      freq 3
      pos 353
      pos 357
      pos 7638
    doc 3
      freq 2
      pos 324
      pos 5943
    doc 4
      freq 1
      pos 6099
    doc 10
      freq 3
      pos 266
      pos 8031
      pos 8311
    doc 11
      freq 3
      pos 281
      pos 5067
      pos 5327
    doc 12
      freq 1
      pos 7883
    doc 13
      freq 1
      pos 7416
    doc 14
      freq 1
      pos 5881
    skipList 
      level 0
        skipDoc 13
        skipDocFP 93533
        impacts 
          impact 
            freq 2
            norm 107
          impact 
            freq 3
            norm 113
        impactsEnd 
  term 23.4.2
    doc 10
      freq 1
      pos 8489
  term 231
    doc 10
      freq 4
      pos 7004
      pos 7150
      pos 7235
      pos 7363
  term 231413434
    doc 11
      freq 1
      pos 5469
  term 2327
    doc 5
      freq 1
      pos 4312
    doc 13
      freq 1
      pos 6768
  term 234
    doc 11
      freq 1
      pos 9080
  term 234234
    doc 11
      freq 1
      pos 2220
  term 234902
    doc 11
      freq 1
      pos 7655
  term 234q098w
    doc 11
      freq 1
      pos 5957
  term 23523
    doc 11
      freq 1
      pos 4482
  term 235448
    doc 11
      freq 1
      pos 7871
  term 238923
    doc 11
      freq 1
      pos 5818
  term 2390
    doc 2
      freq 1
      pos 2982
  term 239232jh3
    doc 11
      freq 1
      pos 4920
  term 23940
    doc 11
      freq 1
      pos 5954
  term 239423mnsadf3j23lj42
    doc 11
      freq 1
      pos 6172
  term 24
    doc 0
      freq 4
      pos 1770
      pos 2046
      pos 4545
      pos 7601
    doc 1
      freq 6
      pos 361
      pos 365
      pos 370
      pos 375
      pos 7888
      pos 9544
    doc 3
      freq 2
      pos 5909
      pos 6278
    doc 4
      freq 1
      pos 6433
    doc 9
      freq 1
      pos 1339
    doc 10
      freq 3
      pos 270
      pos 277
      pos 8465
    doc 11
      freq 2
      pos 289
      pos 5234
    doc 12
      freq 4
      pos 455
      pos 466
      pos 474
      pos 8236
    skipList 
      level 0
        skipDoc 12
        skipDocFP 95116
        impacts 
          impact 
            freq 1
            norm 95
          impact 
            freq 2
            norm 107
          impact 
            freq 6
            norm 113
        impactsEnd 
  term 240
    doc 5
      freq 4
      pos 3781
      pos 3783
      pos 3997
      pos 3999
  term 2401
    doc 4
      freq 1
      pos 5379
  term 241
    doc 5
      freq 2
      pos 3808
      pos 4024
  term 242etr
    doc 11
      freq 1
      pos 7745
  term 2434
    doc 5
      freq 1
      pos 4159
    doc 8
      freq 1
      pos 1743
  term 244
    doc 7
      freq 1
      pos 551
  term 2460
    doc 4
      freq 1
      pos 5189
  term 2461
    doc 4
      freq 1
      pos 5209
  term 2462
    doc 12
      freq 1
      pos 7083
    doc 15
      freq 1
      pos 3920
  term 2463
    doc 4
      freq 9
      pos 11
      pos 278
      pos 433
      pos 435
      pos 5083
      pos 5227
      pos 5247
      pos 5543
      pos 5551
  term 25
    doc 0
      freq 6
      pos 4702
      pos 5390
      pos 5402
      pos 7648
      pos 8081
      pos 8123
    doc 1
      freq 4
      pos 381
      pos 385
      pos 390
      pos 8236
    doc 7
      freq 6
      pos 493
      pos 862
      pos 2136
      pos 2146
      pos 2272
      pos 2529
    doc 10
      freq 1
      pos 8985
    doc 11
      freq 5
      pos 294
      pos 2244
      pos 2827
      pos 2834
      pos 5391
    doc 12
      freq 1
      pos 8633
    doc 17
      freq 1
      pos 2376
  term 2502
    doc 9
      freq 1
      pos 1787
  term 254
    doc 8
      freq 3
      pos 888
      pos 1213
      pos 1394
    doc 11
      freq 1
      pos 4670
  term 2543
    doc 11
      freq 4
      pos 528
      pos 7093
      pos 9149
      pos 9158
  term 255
    doc 0
      freq 5
      pos 2089
      pos 6503
      pos 12260
      pos 12603
      pos 12727
    doc 2
      freq 1
      pos 1658
    doc 4
      freq 5
      pos 733
      pos 823
      pos 885
      pos 936
      pos 5163
    doc 5
      freq 2
      pos 3810
      pos 4026
    doc 8
      freq 3
      pos 869
      pos 1195
      pos 1376
    doc 11
      freq 2
      pos 1992
      pos 4772
    doc 14
      freq 1450
      pos 680
      pos 2380
      pos 2967
      pos 2968
      pos 2969
      pos 2970
      pos 2971
      pos 2972
      pos 2973
      pos 2974
      pos 2975
      pos 2976
      pos 2977
      pos 2978
      pos 2979
      pos 2980
      pos 2981
      pos 2982
      pos 2983
      pos 2984
      pos 2985
      pos 2986
      pos 2987
      pos 2988
      pos 2989
      pos 2990
      pos 2991
      pos 2992
      pos 2993
      pos 2994
      pos 2995
      pos 2996
      pos 2997
      pos 2998
      pos 2999
      pos 3000
      pos 3001
      pos 3002
      pos 3003
      pos 3004
      pos 3005
      pos 3006
      pos 3007
      pos 3008
      pos 3009
      pos 3010
      pos 3011
      pos 3012
      pos 3013
      pos 3014
      pos 3015
      pos 3016
      pos 3017
      pos 3018
      pos 3019
      pos 3020
      pos 3021
      pos 3022
      pos 3023
      pos 3024
      pos 3025
      pos 3026
      pos 3027
      pos 3028
      pos 3029
      pos 3030
      pos 3031
      pos 3032
      pos 3033
      pos 3034
      pos 3035
      pos 3036
      pos 3037
      pos 3038
      pos 3039
      pos 3040
      pos 3041
      pos 3042
      pos 3043
      pos 3044
      pos 3045
      pos 3046
      pos 3047
      pos 3048
      pos 3049
      pos 3050
      pos 3051
      pos 3052
      pos 3053
      pos 3054
      pos 3055
      pos 3056
      pos 3057
      pos 3058
      pos 3059
      pos 3060
      pos 3061
      pos 3062
      pos 3063
      pos 3064
      pos 3065
      pos 3066
      pos 3067
      pos 3068
      pos 3069
      pos 3070
      pos 3071
      pos 3072
      pos 3073
      pos 3074
      pos 3075
      pos 3076
      pos 3077
      pos 3078
      pos 3079
      pos 3080
      pos 3081
      pos 3082
      pos 3083
      pos 3084
      pos 3085
      pos 3086
      pos 3087
      pos 3088
      pos 3089
      pos 3090
      pos 3091
      pos 3092
      pos 3093
      pos 3094
      pos 3095
      pos 3096
      pos 3097
      pos 3098
      pos 3099
      pos 3100
      pos 3101
      pos 3102
      pos 3103
      pos 3104
      pos 3105
      pos 3106
      pos 3107
      pos 3108
      pos 3109
      pos 3110
      pos 3111
      pos 3112
      pos 3113
      pos 3114
      pos 3115
      pos 3116
      pos 3117
      pos 3118
      pos 3119
      pos 3120
      pos 3121
      pos 3122
      pos 3123
      pos 3124
      pos 3125
      pos 3126
      pos 3127
      pos 3128
      pos 3129
      pos 3130
      pos 3131
      pos 3132
      pos 3133
      pos 3134
      pos 3135
      pos 3136
      pos 3137
      pos 3138
      pos 3139
      pos 3140
      pos 3141
      pos 3143
      pos 3144
      pos 3145
      pos 3146
      pos 3147
      pos 3148
      pos 3149
      pos 3150
      pos 3151
      pos 3152
      pos 3153
      pos 3154
      pos 3155
      pos 3156
      pos 3157
      pos 3158
      pos 3159
      pos 3160
      pos 3161
      pos 3162
      pos 3163
      pos 3164
      pos 3165
      pos 3166
      pos 3167
      pos 3168
      pos 3169
      pos 3170
      pos 3171
      pos 3172
      pos 3173
      pos 3174
      pos 3175
      pos 3176
      pos 3177
      pos 3178
      pos 3179
      pos 3180
      pos 3181
      pos 3182
      pos 3183
      pos 3184
      pos 3185
      pos 3186
      pos 3187
      pos 3188
      pos 3189
      pos 3190
      pos 3191
      pos 3192
      pos 3193
      pos 3194
      pos 3195
      pos 3196
      pos 3197
      pos 3198
      pos 3199
      pos 3200
      pos 3201
      pos 3202
      pos 3208
      pos 3210
      pos 3212
      pos 3215
      pos 3288
      pos 3289
      pos 3290
      pos 3291
      pos 3292
      pos 3293
      pos 3294
      pos 3295
      pos 3296
      pos 3297
      pos 3298
      pos 3299
      pos 3300
      pos 3301
      pos 3302
      pos 3303
      pos 3304
      pos 3305
      pos 3306
      pos 3307
      pos 3308
      pos 3309
      pos 3310
      pos 3311
      pos 3312
      pos 3313
      pos 3314
      pos 3315
      pos 3316
      pos 3317
      pos 3318
      pos 3319
      pos 3320
      pos 3321
      pos 3322
      pos 3323
      pos 3324
      pos 3325
      pos 3326
      pos 3327
      pos 3328
      pos 3329
      pos 3330
      pos 3331
      pos 3332
      pos 3333
      pos 3334
      pos 3335
      pos 3336
      pos 3337
      pos 3338
      pos 3339
      pos 3340
      pos 3341
      pos 3342
      pos 3343
      pos 3344
      pos 3345
      pos 3346
      pos 3347
      pos 3348
      pos 3349
      pos 3350
      pos 3351
      pos 3352
      pos 3353
      pos 3354
      pos 3355
      pos 3356
      pos 3357
      pos 3358
      pos 3359
      pos 3360
      pos 3361
      pos 3362
      pos 3363
      pos 3364
      pos 3365
      pos 3366
      pos 3367
      pos 3368
      pos 3369
      pos 3370
      pos 3371
      pos 3372
      pos 3373
      pos 3374
      pos 3375
      pos 3376
      pos 3377
      pos 3378
      pos 3379
      pos 3380
      pos 3381
      pos 3382
      pos 3383
      pos 3384
      pos 3385
      pos 3386
      pos 3387
      pos 3388
      pos 3389
      pos 3390
      pos 3391
      pos 3392
      pos 3393
      pos 3394
      pos 3395
      pos 3396
      pos 3397
      pos 3398
      pos 3399
      pos 3400
      pos 3401
      pos 3402
      pos 3403
      pos 3404
      pos 3405
      pos 3406
      pos 3407
      pos 3408
      pos 3409
      pos 3410
      pos 3411
      pos 3412
      pos 3413
      pos 3414
      pos 3415
      pos 3416
      pos 3417
      pos 3418
      pos 3419
      pos 3420
      pos 3421
      pos 3422
      pos 3423
      pos 3424
      pos 3425
      pos 3426
      pos 3427
      pos 3428
      pos 3429
      pos 3430
      pos 3431
      pos 3432
      pos 3433
      pos 3434
      pos 3435
      pos 3436
      pos 3437
      pos 3438
      pos 3439
      pos 3440
      pos 3441
      pos 3442
      pos 3443
      pos 3444
      pos 3445
      pos 3446
      pos 3447
      pos 3448
      pos 3449
      pos 3450
      pos 3451
      pos 3452
      pos 3453
      pos 3454
      pos 3455
      pos 3456
      pos 3457
      pos 3458
      pos 3459
      pos 3460
      pos 3461
      pos 3462
      pos 3463
      pos 3464
      pos 3465
      pos 3466
      pos 3467
      pos 3468
      pos 3469
      pos 3470
      pos 3471
      pos 3472
      pos 3473
      pos 3474
      pos 3475
      pos 3476
      pos 3477
      pos 3478
      pos 3479
      pos 3480
      pos 3481
      pos 3482
      pos 3483
      pos 3484
      pos 3485
      pos 3486
      pos 3487
      pos 3488
      pos 3489
      pos 3490
      pos 3491
      pos 3492
      pos 3493
      pos 3494
      pos 3495
      pos 3496
      pos 3497
      pos 3498
      pos 3499
      pos 3500
      pos 3501
      pos 3502
      pos 3503
      pos 3504
      pos 3505
      pos 3506
      pos 3507
      pos 3508
      pos 3509
      pos 3510
      pos 3511
      pos 3512
      pos 3513
      pos 3514
      pos 3515
      pos 3516
      pos 3517
      pos 3518
      pos 3519
      pos 3520
      pos 3521
      pos 3527
      pos 3529
      pos 3531
      pos 3533
      pos 3573
      pos 3574
      pos 3575
      pos 3576
      pos 3577
      pos 3578
      pos 3579
      pos 3580
      pos 3581
      pos 3582
      pos 3583
      pos 3584
      pos 3585
      pos 3586
      pos 3587
      pos 3588
      pos 3589
      pos 3590
      pos 3591
      pos 3592
      pos 3593
      pos 3594
      pos 3595
      pos 3596
      pos 3597
      pos 3598
      pos 3599
      pos 3600
      pos 3601
      pos 3602
      pos 3603
      pos 3604
      pos 3605
      pos 3606
      pos 3607
      pos 3608
      pos 3609
      pos 3610
      pos 3611
      pos 3612
      pos 3613
      pos 3614
      pos 3615
      pos 3616
      pos 3617
      pos 3618
      pos 3619
      pos 3620
      pos 3621
      pos 3622
      pos 3623
      pos 3624
      pos 3625
      pos 3626
      pos 3627
      pos 3628
      pos 3629
      pos 3630
      pos 3631
      pos 3632
      pos 3633
      pos 3634
      pos 3635
      pos 3636
      pos 3637
      pos 3638
      pos 3639
      pos 3640
      pos 3641
      pos 3642
      pos 3643
      pos 3644
      pos 3645
      pos 3646
      pos 3647
      pos 3648
      pos 3649
      pos 3650
      pos 3651
      pos 3652
      pos 3653
      pos 3654
      pos 3655
      pos 3656
      pos 3657
      pos 3658
      pos 3659
      pos 3660
      pos 3661
      pos 3662
      pos 3663
      pos 3664
      pos 3665
      pos 3666
      pos 3667
      pos 3668
      pos 3669
      pos 3670
      pos 3671
      pos 3672
      pos 3673
      pos 3674
      pos 3675
      pos 3676
      pos 3677
      pos 3678
      pos 3679
      pos 3680
      pos 3681
      pos 3682
      pos 3683
      pos 3684
      pos 3685
      pos 3686
      pos 3687
      pos 3688
      pos 3689
      pos 3690
      pos 3691
      pos 3692
      pos 3693
      pos 3694
      pos 3695
      pos 3696
      pos 3697
      pos 3698
      pos 3699
      pos 3700
      pos 3701
      pos 3702
      pos 3703
      pos 3704
      pos 3705
      pos 3706
      pos 3707
      pos 3708
      pos 3709
      pos 3710
      pos 3711
      pos 3712
      pos 3713
      pos 3714
      pos 3715
      pos 3716
      pos 3717
      pos 3718
      pos 3719
      pos 3720
      pos 3721
      pos 3722
      pos 3723
      pos 3724
      pos 3725
      pos 3726
      pos 3727
      pos 3728
      pos 3729
      pos 3730
      pos 3731
      pos 3732
      pos 3733
      pos 3734
      pos 3735
      pos 3736
      pos 3737
      pos 3738
      pos 3739
      pos 3740
      pos 3741
      pos 3742
      pos 3743
      pos 3744
      pos 3745
      pos 3746
      pos 3747
      pos 3749
      pos 3750
      pos 3751
      pos 3752
      pos 3753
      pos 3754
      pos 3755
      pos 3756
      pos 3757
      pos 3758
      pos 3759
      pos 3760
      pos 3761
      pos 3762
      pos 3763
      pos 3764
      pos 3765
      pos 3766
      pos 3767
      pos 3768
      pos 3769
      pos 3770
      pos 3771
      pos 3772
      pos 3773
      pos 3774
      pos 3775
      pos 3776
      pos 3777
      pos 3778
      pos 3779
      pos 3780
      pos 3781
      pos 3782
      pos 3783
      pos 3784
      pos 3785
      pos 3786
      pos 3787
      pos 3788
      pos 3789
      pos 3790
      pos 3791
      pos 3792
      pos 3793
      pos 3794
      pos 3795
      pos 3796
      pos 3797
      pos 3798
      pos 3799
      pos 3800
      pos 3801
      pos 3802
      pos 3803
      pos 3804
      pos 3805
      pos 3806
      pos 3807
      pos 3808
      pos 3814
      pos 3816
      pos 3818
      pos 3821
      pos 3878
      pos 3879
      pos 3880
      pos 3881
      pos 3882
      pos 3883
      pos 3884
      pos 3885
      pos 3886
      pos 3887
      pos 3888
      pos 3889
      pos 3890
      pos 3891
      pos 3892
      pos 3893
      pos 3894
      pos 3895
      pos 3896
      pos 3897
      pos 3898
      pos 3899
      pos 3900
      pos 3901
      pos 3902
      pos 3903
      pos 3904
      pos 3905
      pos 3906
      pos 3907
      pos 3908
      pos 3909
      pos 3910
      pos 3911
      pos 3912
      pos 3913
      pos 3914
      pos 3915
      pos 3916
      pos 3917
      pos 3918
      pos 3919
      pos 3920
      pos 3921
      pos 3922
      pos 3923
      pos 3924
      pos 3925
      pos 3926
      pos 3927
      pos 3928
      pos 3929
      pos 3930
      pos 3931
      pos 3932
      pos 3933
      pos 3934
      pos 3935
      pos 3936
      pos 3937
      pos 3938
      pos 3939
      pos 3940
      pos 3941
      pos 3942
      pos 3943
      pos 3944
      pos 3945
      pos 3946
      pos 3947
      pos 3948
      pos 3949
      pos 3950
      pos 3951
      pos 3952
      pos 3953
      pos 3954
      pos 3955
      pos 3956
      pos 3957
      pos 3958
      pos 3959
      pos 3960
      pos 3961
      pos 3962
      pos 3963
      pos 3964
      pos 3965
      pos 3966
      pos 3967
      pos 3968
      pos 3969
      pos 3970
      pos 3971
      pos 3972
      pos 3973
      pos 3974
      pos 3975
      pos 3976
      pos 3977
      pos 3978
      pos 3979
      pos 3980
      pos 3981
      pos 3982
      pos 3983
      pos 3984
      pos 3985
      pos 3986
      pos 3987
      pos 3988
      pos 3989
      pos 3990
      pos 3991
      pos 3992
      pos 3993
      pos 3994
      pos 3995
      pos 3996
      pos 3997
      pos 3998
      pos 3999
      pos 4000
      pos 4001
      pos 4002
      pos 4003
      pos 4004
      pos 4005
      pos 4006
      pos 4007
      pos 4008
      pos 4009
      pos 4010
      pos 4011
      pos 4012
      pos 4013
      pos 4014
      pos 4015
      pos 4016
      pos 4017
      pos 4018
      pos 4019
      pos 4020
      pos 4021
      pos 4022
      pos 4023
      pos 4024
      pos 4025
      pos 4026
      pos 4027
      pos 4028
      pos 4029
      pos 4030
      pos 4031
      pos 4032
      pos 4033
      pos 4034
      pos 4035
      pos 4036
      pos 4037
      pos 4038
      pos 4039
      pos 4040
      pos 4041
      pos 4042
      pos 4043
      pos 4044
      pos 4045
      pos 4046
      pos 4047
      pos 4048
      pos 4049
      pos 4050
      pos 4051
      pos 4052
      pos 4053
      pos 4054
      pos 4055
      pos 4056
      pos 4057
      pos 4058
      pos 4059
      pos 4060
      pos 4061
      pos 4062
      pos 4063
      pos 4064
      pos 4065
      pos 4066
      pos 4067
      pos 4068
      pos 4069
      pos 4070
      pos 4071
      pos 4072
      pos 4073
      pos 4074
      pos 4075
      pos 4076
      pos 4077
      pos 4078
      pos 4079
      pos 4080
      pos 4081
      pos 4082
      pos 4083
      pos 4084
      pos 4085
      pos 4086
      pos 4087
      pos 4088
      pos 4089
      pos 4090
      pos 4091
      pos 4092
      pos 4093
      pos 4094
      pos 4095
      pos 4096
      pos 4097
      pos 4098
      pos 4099
      pos 4100
      pos 4101
      pos 4102
      pos 4103
      pos 4104
      pos 4105
      pos 4106
      pos 4107
      pos 4108
      pos 4109
      pos 4110
      pos 4111
      pos 4112
      pos 4113
      pos 4114
      pos 4115
      pos 4121
      pos 4123
      pos 4125
      pos 4127
      pos 4318
      pos 4319
      pos 4320
      pos 4321
      pos 4322
      pos 4323
      pos 4324
      pos 4325
      pos 4326
      pos 4327
      pos 4328
      pos 4329
      pos 4330
      pos 4331
      pos 4332
      pos 4333
      pos 4334
      pos 4335
      pos 4336
      pos 4337
      pos 4338
      pos 4339
      pos 4340
      pos 4341
      pos 4342
      pos 4343
      pos 4344
      pos 4345
      pos 4346
      pos 4347
      pos 4348
      pos 4349
      pos 4350
      pos 4351
      pos 4352
      pos 4353
      pos 4354
      pos 4355
      pos 4356
      pos 4357
      pos 4358
      pos 4359
      pos 4360
      pos 4361
      pos 4362
      pos 4363
      pos 4364
      pos 4365
      pos 4366
      pos 4376
      pos 4449
      pos 4450
      pos 4451
      pos 4452
      pos 4453
      pos 4454
      pos 4455
      pos 4456
      pos 4468
      pos 4618
      pos 4619
      pos 4620
      pos 4621
      pos 4622
      pos 4623
      pos 4624
      pos 4625
      pos 4626
      pos 4627
      pos 4628
      pos 4629
      pos 4630
      pos 4631
      pos 4632
      pos 4633
      pos 4634
      pos 4635
      pos 4636
      pos 4637
      pos 4638
      pos 4639
      pos 4640
      pos 4641
      pos 4642
      pos 4643
      pos 4644
      pos 4645
      pos 4646
      pos 4647
      pos 4648
      pos 4649
      pos 4650
      pos 4651
      pos 4652
      pos 4653
      pos 4654
      pos 4655
      pos 4656
      pos 4657
      pos 4658
      pos 4659
      pos 4660
      pos 4661
      pos 4662
      pos 4663
      pos 4664
      pos 4665
      pos 4666
      pos 4667
      pos 4668
      pos 4669
      pos 4670
      pos 4671
      pos 4672
      pos 4673
      pos 4674
      pos 4675
      pos 4676
      pos 4677
      pos 4678
      pos 4679
      pos 4680
      pos 4681
      pos 4682
      pos 4683
      pos 4684
      pos 4685
      pos 4686
      pos 4687
      pos 4688
      pos 4689
      pos 4690
      pos 4691
      pos 4692
      pos 4693
      pos 4694
      pos 4695
      pos 4696
      pos 4697
      pos 4698
      pos 4699
      pos 4700
      pos 4701
      pos 4702
      pos 4703
      pos 4704
      pos 4705
      pos 4706
      pos 4707
      pos 4708
      pos 4709
      pos 4710
      pos 4711
      pos 4712
      pos 4713
      pos 4714
      pos 4715
      pos 4716
      pos 4717
      pos 4718
      pos 4719
      pos 4720
      pos 4721
      pos 4722
      pos 4723
      pos 4724
      pos 4725
      pos 4726
      pos 4727
      pos 4728
      pos 4729
      pos 4730
      pos 4731
      pos 4732
      pos 4733
      pos 4734
      pos 4735
      pos 4736
      pos 4737
      pos 4738
      pos 4739
      pos 4740
      pos 4741
      pos 4742
      pos 4743
      pos 4744
      pos 4745
      pos 4746
      pos 4747
      pos 4748
      pos 4749
      pos 4750
      pos 4751
      pos 4752
      pos 4753
      pos 4754
      pos 4755
      pos 4756
      pos 4757
      pos 4758
      pos 4759
      pos 4760
      pos 4761
      pos 4762
      pos 4763
      pos 4764
      pos 4765
      pos 4766
      pos 4767
      pos 4768
      pos 4769
      pos 4770
      pos 4771
      pos 4772
      pos 4773
      pos 4774
      pos 4775
      pos 4776
      pos 4777
      pos 4778
      pos 4779
      pos 4780
      pos 4781
      pos 4782
      pos 4783
      pos 4784
      pos 4785
      pos 4786
      pos 4787
      pos 4788
      pos 4789
      pos 4790
      pos 4791
      pos 4792
      pos 4793
      pos 4794
      pos 4795
      pos 4796
      pos 4797
      pos 4798
      pos 4799
      pos 4800
      pos 4801
      pos 4802
      pos 4803
      pos 4804
      pos 4805
      pos 4806
      pos 4807
      pos 4808
      pos 4809
      pos 4810
      pos 4811
      pos 4812
      pos 4813
      pos 4814
      pos 4815
      pos 4816
      pos 4817
      pos 4818
      pos 4819
      pos 4820
      pos 4821
      pos 4822
      pos 4823
      pos 4824
      pos 4825
      pos 4826
      pos 4827
      pos 4828
      pos 4829
      pos 4830
      pos 4831
      pos 4832
      pos 4833
      pos 4834
      pos 4835
      pos 4836
      pos 4837
      pos 4838
      pos 4839
      pos 4840
      pos 4841
      pos 4842
      pos 4843
      pos 4844
      pos 4845
      pos 4846
      pos 4847
      pos 4848
      pos 4849
      pos 4850
      pos 4851
      pos 4852
      pos 4853
      pos 4854
      pos 4855
      pos 4861
      pos 4863
      pos 4865
      pos 4867
      pos 4888
      pos 4889
      pos 4890
      pos 4891
      pos 4892
      pos 4893
      pos 4894
      pos 4895
      pos 4896
      pos 4897
      pos 4898
      pos 4899
      pos 4900
      pos 4901
      pos 4902
      pos 4903
      pos 4904
      pos 4905
      pos 4906
      pos 4907
      pos 4908
      pos 4909
      pos 4910
      pos 4911
      pos 4912
      pos 4913
      pos 4914
      pos 4915
      pos 4916
      pos 4917
      pos 4918
      pos 4919
      pos 4920
      pos 4921
      pos 4922
      pos 4923
      pos 4924
      pos 4925
      pos 4926
      pos 4927
      pos 4928
      pos 4929
      pos 4930
      pos 4931
      pos 4932
      pos 4933
      pos 4934
      pos 4935
      pos 4936
      pos 4937
      pos 4938
      pos 4939
      pos 4940
      pos 4941
      pos 4942
      pos 4943
      pos 4944
      pos 4945
      pos 4946
      pos 4947
      pos 4954
      pos 5056
      pos 5057
      pos 5058
      pos 5059
      pos 5060
      pos 5061
      pos 5062
      pos 5063
      pos 5064
      pos 5065
      pos 5066
      pos 5067
      pos 5068
      pos 5069
      pos 5070
      pos 5071
      pos 5072
      pos 5073
      pos 5074
      pos 5075
      pos 5076
      pos 5077
      pos 5078
      pos 5079
      pos 5080
      pos 5081
      pos 5082
      pos 5083
      pos 5084
      pos 5085
      pos 5086
      pos 5087
      pos 5088
      pos 5089
      pos 5090
      pos 5091
      pos 5092
      pos 5093
      pos 5094
      pos 5095
      pos 5096
      pos 5097
      pos 5098
      pos 5099
      pos 5100
      pos 5101
      pos 5102
      pos 5103
      pos 5104
      pos 5105
      pos 5106
      pos 5107
      pos 5108
      pos 5109
      pos 5110
      pos 5111
      pos 5112
      pos 5113
      pos 5114
      pos 5115
      pos 5116
      pos 5117
      pos 5118
      pos 5124
      pos 5200
      pos 5201
      pos 5202
      pos 5203
      pos 5204
      pos 5205
      pos 5206
      pos 5207
      pos 5208
      pos 5209
      pos 5210
      pos 5211
      pos 5212
      pos 5213
      pos 5214
      pos 5215
      pos 5216
      pos 5217
      pos 5218
      pos 5219
      pos 5220
      pos 5221
      pos 5222
      pos 5223
      pos 5224
      pos 5225
      pos 5226
      pos 5227
      pos 5228
      pos 5229
      pos 5230
      pos 5231
      pos 5232
      pos 5233
      pos 5234
      pos 5235
      pos 5236
      pos 5237
      pos 5238
      pos 5239
      pos 5240
      pos 5241
      pos 5242
      pos 5243
      pos 5244
      pos 5245
      pos 5246
      pos 5247
      pos 5248
      pos 5249
      pos 5250
      pos 5251
      pos 5252
      pos 5253
      pos 5254
      pos 5255
      pos 5256
      pos 5257
      pos 5258
      pos 5259
      pos 5260
      pos 5261
      pos 5262
      pos 5268
    doc 16
      freq 1
      pos 2198
    doc 18
      freq 123
      pos 1318
      pos 1391
      pos 1392
      pos 1393
      pos 1394
      pos 1395
      pos 1396
      pos 1397
      pos 1398
      pos 1399
      pos 1400
      pos 1401
      pos 1402
      pos 1403
      pos 1404
      pos 1405
      pos 1406
      pos 1407
      pos 1408
      pos 1409
      pos 1410
      pos 1411
      pos 1412
      pos 1413
      pos 1414
      pos 1415
      pos 1416
      pos 1417
      pos 1418
      pos 1419
      pos 1420
      pos 1421
      pos 1422
      pos 1423
      pos 1424
      pos 1425
      pos 1426
      pos 1427
      pos 1428
      pos 1429
      pos 1430
      pos 1431
      pos 1432
      pos 1433
      pos 1434
      pos 1435
      pos 1436
      pos 1437
      pos 1438
      pos 1439
      pos 1440
      pos 1441
      pos 1442
      pos 1443
      pos 1444
      pos 1445
      pos 1446
      pos 1447
      pos 1448
      pos 1449
      pos 1450
      pos 1459
      pos 1460
      pos 1461
      pos 1462
      pos 1463
      pos 1464
      pos 1465
      pos 1466
      pos 1467
      pos 1468
      pos 1469
      pos 1470
      pos 1471
      pos 1472
      pos 1473
      pos 1474
      pos 1475
      pos 1476
      pos 1477
      pos 1478
      pos 1479
      pos 1480
      pos 1481
      pos 1482
      pos 1483
      pos 1484
      pos 1485
      pos 1486
      pos 1487
      pos 1488
      pos 1489
      pos 1490
      pos 1491
      pos 1492
      pos 1493
      pos 1494
      pos 1495
      pos 1496
      pos 1497
      pos 1498
      pos 1499
      pos 1500
      pos 1501
      pos 1502
      pos 1503
      pos 1504
      pos 1505
      pos 1506
      pos 1507
      pos 1508
      pos 1509
      pos 1510
      pos 1511
      pos 1512
      pos 1513
      pos 1514
      pos 1515
      pos 1516
      pos 1517
      pos 1518
      pos 1519
      pos 1520
    skipList 
      level 0
        skipDoc 16
        skipDocFP 97473
        impacts 
          impact 
            freq 3
            norm 97
          impact 
            freq 1450
            norm 107
        impactsEnd 
  term 255.255.255.255
    doc 11
      freq 2
      pos 8394
      pos 8482
  term 2556
    doc 7
      freq 1
      pos 257
  term 2578
    doc 0
      freq 2
      pos 286
      pos 17057
  term 2579
    doc 0
      freq 2
      pos 291
      pos 17075
  term 2580
    doc 0
      freq 2
      pos 297
      pos 17093
  term 2585
    doc 10
      freq 2
      pos 5620
      pos 13271
  term 25m13xqa2pj9pzebgf8rpvnfsen
    doc 11
      freq 1
      pos 10057
  term 26
    doc 0
      freq 1
      pos 4818
    doc 1
      freq 2
      pos 395
      pos 8704
    doc 2
      freq 2
      pos 1570
      pos 2441
    doc 5
      freq 1
      pos 4157
    doc 8
      freq 1
      pos 1741
    doc 10
      freq 1
      pos 9475
    doc 11
      freq 2
      pos 302
      pos 5539
    doc 12
      freq 2
      pos 484
      pos 9045
    doc 17
      freq 1
      pos 2192
    skipList 
      level 0
        skipDoc 12
        skipDocFP 122265
        impacts 
          impact 
            freq 1
            norm 97
          impact 
            freq 2
            norm 108
        impactsEnd 
  term 26.3.2.2
    doc 10
      freq 1
      pos 1353
  term 2616
    doc 13
      freq 1
      pos 6903
  term 2671
    doc 12
      freq 1
      pos 7095
  term 2674
    doc 2
      freq 1
      pos 3013
  term 26mk7gyb
    doc 10
      freq 1
      pos 12515
  term 27
    doc 0
      freq 1
      pos 5040
    doc 1
      freq 4
      pos 398
      pos 402
      pos 406
      pos 9019
    doc 7
      freq 1
      pos 2925
    doc 10
      freq 2
      pos 283
      pos 9940
    doc 11
      freq 2
      pos 310
      pos 5699
    doc 12
      freq 2
      pos 492
      pos 9417
  term 2726
    doc 6
      freq 1
      pos 3214
  term 274
    doc 3
      freq 2
      pos 4963
      pos 4977
  term 2766
    doc 12
      freq 1
      pos 7485
  term 2780
    doc 4
      freq 7
      pos 15
      pos 439
      pos 441
      pos 5304
      pos 5325
      pos 5879
      pos 5901
  term 2782
    doc 12
      freq 1
      pos 7508
    doc 14
      freq 1
      pos 5425
  term 27it22tdvhytem8mdzwc4zajkqorvk2bbiaaedmhtehrdlvkouclfajslylf
    doc 11
      freq 1
      pos 9876
  term 28
    doc 0
      freq 1
      pos 5234
    doc 1
      freq 3
      pos 411
      pos 9223
      pos 9545
    doc 3
      freq 1
      pos 5910
    doc 10
      freq 2
      pos 292
      pos 10330
    doc 11
      freq 2
      pos 319
      pos 5831
    doc 12
      freq 1
      pos 9468
  term 280297596632815
    doc 11
      freq 1
      pos 4942
  term 2818
    doc 10
      freq 3
      pos 10760
      pos 10766
      pos 13281
  term 2821
    doc 12
      freq 1
      pos 7106
  term 2822
    doc 11
      freq 1
      pos 9626
    doc 16
      freq 2
      pos 1079
      pos 2566
  term 2826
    doc 12
      freq 1
      pos 7524
  term 285
    doc 1
      freq 1
      pos 9236
  term 2863
    doc 0
      freq 1
      pos 16991
  term 2865
    doc 2
      freq 1
      pos 3034
  term 2866
    doc 2
      freq 1
      pos 3043
  term 2867
    doc 2
      freq 1
      pos 3062
  term 2868
    doc 2
      freq 1
      pos 3086
  term 2869
    doc 2
      freq 1
      pos 3100
  term 2890844526
    doc 10
      freq 6
      pos 6377
      pos 6378
      pos 6502
      pos 6503
      pos 6677
      pos 6678
  term 28f26220f7e941749e330d9a15edabdb
    doc 11
      freq 1
      pos 3908
  term 29
    doc 0
      freq 1
      pos 5471
    doc 1
      freq 1
      pos 9330
    doc 7
      freq 1
      pos 544
    doc 10
      freq 2
      pos 298
      pos 10786
    doc 11
      freq 2
      pos 327
      pos 6019
    doc 12
      freq 1
      pos 9801
  term 2923420123
    doc 11
      freq 1
      pos 8170
  term 29344
    doc 11
      freq 1
      pos 2584
  term 2973
    doc 0
      freq 3
      pos 6011
      pos 6073
      pos 17144
  term 29739
    doc 11
      freq 20
      pos 1536
      pos 2254
      pos 3172
      pos 3405
      pos 4048
      pos 4313
      pos 4494
      pos 4708
      pos 5199
      pos 5356
      pos 5504
      pos 5664
      pos 5984
      pos 6208
      pos 6898
      pos 7232
      pos 8188
      pos 8517
      pos 9112
      pos 9289
  term 2974
    doc 13
      freq 1
      pos 6783
  term 2983792873
    doc 11
      freq 1
      pos 7642
  term 2986
    doc 9
      freq 1
      pos 1782
  term 2992
    doc 3
      freq 1
      pos 4693
  term 29b
    doc 10
      freq 1
      pos 12594
  term 29nu2wts4dvxvqbu
    doc 11
      freq 1
      pos 10356
  term 2a864886f70d01010105000481808ef4
    doc 11
      freq 1
      pos 3904
  term 2aue3h
    doc 10
      freq 1
      pos 12648
  term 2bl
    doc 11
      freq 1
      pos 10289
  term 2cjhi5g96xxsnqueg3ez5lj1acuoihlrzetz7vlaxvqugwnil2
    doc 11
      freq 1
      pos 10239
  term 2easdjfejw
    doc 11
      freq 1
      pos 5044
  term 2fb0dcc9
    doc 11
      freq 1
      pos 3821
  term 2fo7exzicvar3yuptxb0t7
    doc 10
      freq 1
      pos 12651
  term 2ichfbqzckxqnakujslptfgolf9sthot7rqpatkjscbblcq
    doc 11
      freq 1
      pos 10334
  term 2k
    doc 6
      freq 1
      pos 1904
  term 2nd
    doc 11
      freq 2
      pos 3599
      pos 8386
  term 2p1
    doc 11
      freq 1
      pos 10012
  term 2pi7f0yr
    doc 11
      freq 1
      pos 9925
  term 2rc1fcywfomerfko3oymkycef
    doc 10
      freq 1
      pos 12541
  term 2sk
    doc 10
      freq 1
      pos 12676
  term 2tyoevqvtisv3j
    doc 10
      freq 1
      pos 12802
  term 2w3bbt8l9b2ialsecuqrki05c9fi2lb2a7i169jdgukxkfv
    doc 11
      freq 1
      pos 10352
  term 2yynd2wflgova6bjlgz6pcnfp5rh
    doc 11
      freq 1
      pos 10139
  term 2zu
    doc 11
      freq 1
      pos 10034
  term 3
    doc 0
      freq 44
      pos 151
      pos 659
      pos 949
      pos 1305
      pos 1652
      pos 1788
      pos 1882
      pos 1948
      pos 2461
      pos 2520
      pos 3101
      pos 3108
      pos 3403
      pos 3877
      pos 4377
      pos 4607
      pos 4860
      pos 5642
      pos 5727
      pos 5943
      pos 6464
      pos 7407
      pos 7844
      pos 7962
      pos 8296
      pos 8491
      pos 8974
      pos 9007
      pos 9047
      pos 9095
      pos 9166
      pos 9626
      pos 9789
      pos 10192
      pos 10240
      pos 11241
      pos 11658
      pos 11860
      pos 12213
      pos 12380
      pos 12649
      pos 12998
      pos 15399
      pos 15588
    doc 1
      freq 40
      pos 22
      pos 216
      pos 222
      pos 834
      pos 1186
      pos 2453
      pos 2457
      pos 2467
      pos 2477
      pos 3639
      pos 3643
      pos 3653
      pos 3663
      pos 4001
      pos 4005
      pos 4015
      pos 4025
      pos 4077
      pos 4081
      pos 4091
      pos 4101
      pos 5067
      pos 5071
      pos 5081
      pos 5091
      pos 5236
      pos 5240
      pos 5250
      pos 5260
      pos 5698
      pos 5702
      pos 5712
      pos 5722
      pos 6033
      pos 6037
      pos 6047
      pos 6057
      pos 9209
      pos 9241
      pos 9526
    doc 2
      freq 9
      pos 128
      pos 133
      pos 158
      pos 1073
      pos 2224
      pos 2525
      pos 2542
      pos 2581
      pos 2598
    doc 3
      freq 27
      pos 22
      pos 181
      pos 187
      pos 578
      pos 909
      pos 1263
      pos 3634
      pos 3638
      pos 3648
      pos 3658
      pos 4407
      pos 4429
      pos 4473
      pos 4726
      pos 5041
      pos 5080
      pos 5163
      pos 5268
      pos 5681
      pos 5720
      pos 5729
      pos 5738
      pos 5739
      pos 5748
      pos 5758
      pos 5769
      pos 5891
    doc 4
      freq 50
      pos 159
      pos 164
      pos 181
      pos 589
      pos 593
      pos 603
      pos 613
      pos 740
      pos 776
      pos 980
      pos 1661
      pos 1741
      pos 1776
      pos 2084
      pos 2095
      pos 2099
      pos 2109
      pos 2119
      pos 2185
      pos 2464
      pos 2505
      pos 2761
      pos 2765
      pos 2775
      pos 2785
      pos 3006
      pos 3010
      pos 3020
      pos 3030
      pos 3077
      pos 3242
      pos 3246
      pos 3256
      pos 3266
      pos 3549
      pos 3553
      pos 3563
      pos 3573
      pos 3720
      pos 3724
      pos 3734
      pos 3744
      pos 4321
      pos 4401
      pos 4962
      pos 5261
      pos 5581
      pos 5649
      pos 6005
      pos 6048
    doc 5
      freq 20
      pos 259
      pos 263
      pos 786
      pos 1076
      pos 1306
      pos 1490
      pos 1575
      pos 1579
      pos 1589
      pos 1599
      pos 1797
      pos 1801
      pos 1811
      pos 1821
      pos 1927
      pos 2612
      pos 2616
      pos 2626
      pos 2636
      pos 4294
    doc 6
      freq 3
      pos 650
      pos 1129
      pos 1140
    doc 7
      freq 7
      pos 125
      pos 459
      pos 950
      pos 1532
      pos 1811
      pos 1929
      pos 2017
    doc 8
      freq 5
      pos 116
      pos 129
      pos 334
      pos 796
      pos 956
    doc 9
      freq 9
      pos 124
      pos 131
      pos 472
      pos 669
      pos 815
      pos 933
      pos 1080
      pos 1085
      pos 1684
    doc 10
      freq 11
      pos 183
      pos 186
      pos 187
      pos 189
      pos 711
      pos 786
      pos 3141
      pos 4191
      pos 4482
      pos 7789
      pos 13135
    doc 11
      freq 16
      pos 100
      pos 104
      pos 122
      pos 818
      pos 1136
      pos 1188
      pos 3525
      pos 3999
      pos 5006
      pos 7115
      pos 7391
      pos 7522
      pos 8843
      pos 9760
      pos 9912
      pos 9977
    doc 12
      freq 12
      pos 150
      pos 158
      pos 210
      pos 486
      pos 862
      pos 1615
      pos 2562
      pos 2629
      pos 3392
      pos 4501
      pos 6254
      pos 9055
    doc 13
      freq 15
      pos 137
      pos 142
      pos 156
      pos 450
      pos 755
      pos 1521
      pos 1757
      pos 3712
      pos 4048
      pos 5255
      pos 5857
      pos 6109
      pos 6235
      pos 6439
      pos 6771
    doc 14
      freq 15
      pos 127
      pos 128
      pos 130
      pos 134
      pos 141
      pos 618
      pos 774
      pos 841
      pos 998
      pos 1240
      pos 1479
      pos 1650
      pos 1953
      pos 2168
      pos 2761
    doc 15
      freq 7
      pos 205
      pos 209
      pos 210
      pos 632
      pos 813
      pos 1699
      pos 3923
    doc 16
      freq 7
      pos 292
      pos 540
      pos 559
      pos 907
      pos 1350
      pos 2121
      pos 2545
    doc 17
      freq 8
      pos 530
      pos 813
      pos 867
      pos 892
      pos 1286
      pos 2174
      pos 2214
      pos 2239
    doc 18
      freq 6
      pos 161
      pos 569
      pos 1028
      pos 1175
      pos 1965
      pos 2103
    skipList 
      level 0
        skipDoc 7
        skipDocFP 127506
        impacts 
          impact 
            freq 7
            norm 100
          impact 
            freq 20
            norm 104
          impact 
            freq 27
            norm 107
          impact 
            freq 50
            norm 108
        impactsEnd 
        skipDoc 15
        skipDocFP 130672
        impacts 
          impact 
            freq 9
            norm 95
          impact 
            freq 15
            norm 107
          impact 
            freq 16
            norm 114
        impactsEnd 
  term 3.1
    doc 3
      freq 1
      pos 4490
    doc 4
      freq 4
      pos 186
      pos 768
      pos 2088
      pos 5719
    doc 6
      freq 1
      pos 1161
    doc 8
      freq 2
      pos 120
      pos 376
    doc 10
      freq 1
      pos 10763
    doc 11
      freq 2
      pos 127
      pos 1192
    doc 12
      freq 3
      pos 216
      pos 1665
      pos 3504
    doc 14
      freq 3
      pos 131
      pos 673
      pos 683
    doc 15
      freq 2
      pos 215
      pos 857
    skipList 
      level 0
        skipDoc 14
        skipDocFP 133160
        impacts 
          impact 
            freq 2
            norm 97
          impact 
            freq 3
            norm 107
          impact 
            freq 4
            norm 108
        impactsEnd 
  term 3.1.1
    doc 11
      freq 2
      pos 132
      pos 1196
    doc 14
      freq 2
      pos 135
      pos 686
  term 3.1.1.1
    doc 11
      freq 2
      pos 136
      pos 1199
  term 3.1.1.10
    doc 11
      freq 2
      pos 222
      pos 3556
  term 3.1.1.11
    doc 11
      freq 2
      pos 229
      pos 3694
  term 3.1.1.12
    doc 11
      freq 2
      pos 234
      pos 3915
  term 3.1.1.13
    doc 11
      freq 2
      pos 239
      pos 4078
  term 3.1.1.2
    doc 11
      freq 2
      pos 142
      pos 1580
  term 3.1.1.3
    doc 11
      freq 2
      pos 149
      pos 2002
  term 3.1.1.4
    doc 11
      freq 2
      pos 157
      pos 2298
  term 3.1.1.5
    doc 11
      freq 2
      pos 163
      pos 2404
  term 3.1.1.6
    doc 11
      freq 2
      pos 173
      pos 2606
  term 3.1.1.7
    doc 11
      freq 2
      pos 197
      pos 2708
  term 3.1.1.8
    doc 11
      freq 2
      pos 204
      pos 3202
  term 3.1.1.9
    doc 11
      freq 2
      pos 213
      pos 3449
  term 3.1.2
    doc 11
      freq 2
      pos 244
      pos 4177
    doc 14
      freq 2
      pos 142
      pos 901
  term 3.1.2.1
    doc 11
      freq 2
      pos 248
      pos 4220
  term 3.1.2.10
    doc 11
      freq 2
      pos 311
      pos 5708
  term 3.1.2.11
    doc 11
      freq 2
      pos 320
      pos 5840
  term 3.1.2.12
    doc 11
      freq 2
      pos 328
      pos 6028
  term 3.1.2.13
    doc 11
      freq 2
      pos 336
      pos 6252
  term 3.1.2.14
    doc 11
      freq 2
      pos 345
      pos 6382
  term 3.1.2.15
    doc 11
      freq 2
      pos 351
      pos 6488
  term 3.1.2.16
    doc 11
      freq 2
      pos 359
      pos 6637
  term 3.1.2.17
    doc 11
      freq 2
      pos 364
      pos 6724
  term 3.1.2.18
    doc 11
      freq 2
      pos 372
      pos 6795
  term 3.1.2.19
    doc 11
      freq 2
      pos 380
      pos 6938
  term 3.1.2.2
    doc 11
      freq 2
      pos 254
      pos 4343
  term 3.1.2.3
    doc 11
      freq 2
      pos 261
      pos 4524
  term 3.1.2.4
    doc 11
      freq 2
      pos 266
      pos 4738
  term 3.1.2.5
    doc 11
      freq 2
      pos 274
      pos 4946
  term 3.1.2.6
    doc 11
      freq 2
      pos 282
      pos 5076
  term 3.1.2.7
    doc 11
      freq 2
      pos 290
      pos 5243
  term 3.1.2.8
    doc 11
      freq 2
      pos 295
      pos 5400
  term 3.1.2.9
    doc 11
      freq 2
      pos 303
      pos 5548
  term 3.2
    doc 4
      freq 4
      pos 191
      pos 775
      pos 1684
      pos 2753
    doc 6
      freq 1
      pos 2036
    doc 8
      freq 2
      pos 125
      pos 480
    doc 11
      freq 2
      pos 385
      pos 7001
    doc 12
      freq 2
      pos 225
      pos 1902
    doc 14
      freq 2
      pos 149
      pos 1118
    doc 15
      freq 2
      pos 220
      pos 1102
  term 3.2.1
    doc 11
      freq 2
      pos 390
      pos 7018
    doc 14
      freq 2
      pos 153
      pos 1380
  term 3.2.2
    doc 14
      freq 2
      pos 160
      pos 1557
  term 3.3
    doc 4
      freq 3
      pos 197
      pos 781
      pos 2999
    doc 6
      freq 1
      pos 2152
    doc 8
      freq 2
      pos 130
      pos 805
    doc 11
      freq 2
      pos 395
      pos 7148
    doc 15
      freq 2
      pos 225
      pos 1202
  term 3.3.1
    doc 5
      freq 1
      pos 2256
    doc 11
      freq 2
      pos 400
      pos 7165
  term 3.3.10
    doc 11
      freq 2
      pos 461
      pos 8369
  term 3.3.11
    doc 11
      freq 2
      pos 472
      pos 8547
  term 3.3.12
    doc 11
      freq 2
      pos 478
      pos 8648
  term 3.3.13
    doc 11
      freq 2
      pos 500
      pos 8763
  term 3.3.14
    doc 11
      freq 2
      pos 507
      pos 8867
  term 3.3.15
    doc 11
      freq 2
      pos 515
      pos 8966
  term 3.3.2
    doc 11
      freq 2
      pos 406
      pos 7276
  term 3.3.3
    doc 11
      freq 2
      pos 413
      pos 7409
  term 3.3.4
    doc 11
      freq 2
      pos 422
      pos 7554
  term 3.3.5
    doc 11
      freq 2
      pos 430
      pos 7672
  term 3.3.6
    doc 11
      freq 2
      pos 436
      pos 7788
  term 3.3.7
    doc 11
      freq 2
      pos 441
      pos 7892
  term 3.3.8
    doc 11
      freq 2
      pos 446
      pos 8074
  term 3.3.9
    doc 11
      freq 2
      pos 455
      pos 8232
  term 3.4
    doc 4
      freq 4
      pos 202
      pos 787
      pos 1704
      pos 3235
    doc 6
      freq 1
      pos 2237
    doc 8
      freq 2
      pos 137
      pos 1132
    doc 11
      freq 2
      pos 520
      pos 9142
    doc 15
      freq 2
      pos 229
      pos 1281
  term 3.4.1
    doc 8
      freq 2
      pos 141
      pos 1135
    doc 11
      freq 2
      pos 524
      pos 9145
  term 3.4.2
    doc 8
      freq 2
      pos 147
      pos 1315
  term 3.4.2.1
    doc 1
      freq 1
      pos 2252
  term 3.5
    doc 8
      freq 2
      pos 154
      pos 1508
    doc 14
      freq 1
      pos 1882
    doc 15
      freq 2
      pos 234
      pos 1336
  term 3.6
    doc 8
      freq 2
      pos 158
      pos 1644
    doc 15
      freq 2
      pos 240
      pos 1424
  term 3.6.1
    doc 0
      freq 2
      pos 1895
      pos 1935
  term 3.6.11
    doc 0
      freq 2
      pos 1897
      pos 1937
  term 3.7
    doc 15
      freq 2
      pos 245
      pos 1520
  term 3.75
    doc 6
      freq 2
      pos 1236
      pos 1248
  term 3.8
    doc 15
      freq 2
      pos 250
      pos 1660
  term 30
    doc 0
      freq 3
      pos 4858
      pos 5585
      pos 7011
    doc 1
      freq 1
      pos 9400
    doc 2
      freq 1
      pos 3704
    doc 8
      freq 1
      pos 505
    doc 10
      freq 2
      pos 304
      pos 11203
    doc 11
      freq 3
      pos 335
      pos 1157
      pos 6243
    doc 12
      freq 1
      pos 9445
    doc 16
      freq 1
      pos 1832
    doc 18
      freq 1
      pos 2179
    skipList 
      level 0
        skipDoc 16
        skipDocFP 139370
        impacts 
          impact 
            freq 1
            norm 97
          impact 
            freq 3
            norm 114
        impactsEnd 
  term 300
    doc 0
      freq 3
      pos 2586
      pos 2833
      pos 7020
    doc 1
      freq 2
      pos 9301
      pos 9582
    doc 11
      freq 1
      pos 4929
    doc 12
      freq 4
      pos 2832
      pos 2837
      pos 2849
      pos 2854
  term 3000
    doc 0
      freq 1
      pos 6924
    doc 13
      freq 1
      pos 7049
  term 3002
    doc 11
      freq 1
      pos 7509
  term 3007
    doc 12
      freq 1
      pos 7120
  term 300c060355040a130573697069743129
    doc 11
      freq 1
      pos 3899
  term 3027060355040b132053697069742054
    doc 11
      freq 1
      pos 3900
  term 3031
    doc 3
      freq 1
      pos 4398
  term 3032
    doc 1
      freq 1
      pos 8950
    doc 8
      freq 1
      pos 2075
  term 30350
    doc 6
      freq 1
      pos 3210
  term 3036
    doc 1
      freq 6
      pos 7769
      pos 7819
      pos 7926
      pos 8423
      pos 8635
      pos 8926
    doc 3
      freq 1
      pos 4624
  term 3041
    doc 12
      freq 2
      pos 1330
      pos 7138
  term 3056
    doc 12
      freq 1
      pos 7155
  term 3082015206092a86
    doc 11
      freq 1
      pos 3891
  term 31
    doc 0
      freq 1
      pos 5767
    doc 1
      freq 2
      pos 419
      pos 9495
    doc 8
      freq 2
      pos 515
      pos 1543
    doc 10
      freq 3
      pos 308
      pos 313
      pos 11541
    doc 11
      freq 42
      pos 344
      pos 350
      pos 1561
      pos 1564
      pos 2246
      pos 2279
      pos 2282
      pos 3197
      pos 3200
      pos 3430
      pos 3433
      pos 4073
      pos 4076
      pos 4338
      pos 4341
      pos 4519
      pos 4522
      pos 4733
      pos 4736
      pos 5224
      pos 5227
      pos 5381
      pos 5384
      pos 5529
      pos 5532
      pos 5689
      pos 5692
      pos 6009
      pos 6012
      pos 6233
      pos 6236
      pos 6479
      pos 6919
      pos 6922
      pos 7257
      pos 7260
      pos 8213
      pos 8216
      pos 8542
      pos 8545
      pos 9137
      pos 9140
  term 3118
    doc 15
      freq 1
      pos 3934
  term 313
    doc 9
      freq 1
      pos 1770
  term 31415
    doc 11
      freq 1
      pos 6627
  term 314159
    doc 10
      freq 3
      pos 6348
      pos 6485
      pos 6633
  term 31417
    doc 11
      freq 1
      pos 6703
  term 3149328700
    doc 11
      freq 2
      pos 5367
      pos 5515
  term 3152
    doc 12
      freq 1
      pos 7168
  term 3162
    doc 2
      freq 1
      pos 3115
  term 3166
    doc 7
      freq 1
      pos 273
  term 3170
    doc 13
      freq 1
      pos 6933
  term 32
    doc 0
      freq 4
      pos 1814
      pos 2468
      pos 5948
      pos 13019
    doc 1
      freq 6
      pos 2408
      pos 2630
      pos 2733
      pos 2907
      pos 4126
      pos 9596
    doc 4
      freq 1
      pos 5616
    doc 8
      freq 2
      pos 1308
      pos 1528
    doc 10
      freq 4
      pos 321
      pos 329
      pos 336
      pos 11836
    doc 11
      freq 7
      pos 358
      pos 363
      pos 4764
      pos 4779
      pos 4789
      pos 4972
      pos 6715
  term 3227
    doc 11
      freq 19
      pos 1558
      pos 2276
      pos 3194
      pos 3427
      pos 4070
      pos 4335
      pos 4516
      pos 4730
      pos 5221
      pos 5378
      pos 5526
      pos 5686
      pos 6006
      pos 6230
      pos 6916
      pos 7254
      pos 8210
      pos 8539
      pos 9134
  term 323
    doc 11
      freq 2
      pos 2687
      pos 3625
  term 3234
    doc 11
      freq 1
      pos 2218
  term 3234233
    doc 11
      freq 1
      pos 7647
  term 32394234
    doc 11
      freq 1
      pos 4678
  term 3261
    doc 5
      freq 1
      pos 4338
    doc 10
      freq 16
      pos 423
      pos 456
      pos 512
      pos 881
      pos 1342
      pos 2417
      pos 2624
      pos 4801
      pos 5078
      pos 5080
      pos 5322
      pos 5781
      pos 8299
      pos 8487
      pos 9229
      pos 13113
    doc 11
      freq 7
      pos 2626
      pos 2660
      pos 4985
      pos 6123
      pos 7028
      pos 9169
      pos 9652
    doc 13
      freq 1
      pos 6851
  term 3263
    doc 10
      freq 3
      pos 10481
      pos 10605
      pos 13165
  term 3264
    doc 11
      freq 1
      pos 9671
  term 3265
    doc 13
      freq 1
      pos 6917
  term 3270
    doc 7
      freq 1
      pos 1913
  term 32766
    doc 8
      freq 1
      pos 557
  term 32767
    doc 8
      freq 1
      pos 539
  term 32768
    doc 1
      freq 1
      pos 7498
  term 3280
    doc 10
      freq 4
      pos 4116
      pos 10990
      pos 10997
      pos 13250
    doc 17
      freq 2
      pos 2070
      pos 2203
  term 3281
    doc 17
      freq 1
      pos 2087
  term 3289
    doc 0
      freq 1
      pos 17011
  term 329429089
    doc 11
      freq 1
      pos 5810
  term 32lhex
    doc 10
      freq 1
      pos 4813
  term 33
    doc 0
      freq 2
      pos 5783
      pos 6176
    doc 1
      freq 1
      pos 9929
    doc 10
      freq 4
      pos 344
      pos 349
      pos 356
      pos 12093
    doc 11
      freq 3
      pos 371
      pos 379
      pos 6929
  term 330113300706052b0e03021a300d0609
    doc 11
      freq 1
      pos 3903
  term 331
    doc 4
      freq 1
      pos 6088
  term 3315
    doc 12
      freq 1
      pos 7193
    doc 15
      freq 2
      pos 125
      pos 3959
  term 332211
    doc 14
      freq 1
      pos 5522
  term 3323
    doc 10
      freq 4
      pos 4481
      pos 7788
      pos 7983
      pos 13148
  term 33242
    doc 11
      freq 2
      pos 3522
      pos 7112
  term 3325
    doc 10
      freq 3
      pos 8039
      pos 8188
      pos 13309
  term 3341
    doc 10
      freq 1
      pos 13450
  term 3363
    doc 12
      freq 1
      pos 7222
  term 3364
    doc 12
      freq 1
      pos 7256
  term 3370
    doc 10
      freq 2
      pos 5522
      pos 13209
  term 33721
    doc 13
      freq 2
      pos 7016
      pos 7032
  term 3373
    doc 0
      freq 2
      pos 9045
      pos 17169
  term 33764
    doc 17
      freq 1
      pos 2380
  term 3393
    doc 6
      freq 2
      pos 96
      pos 3025
  term 34
    doc 0
      freq 1
      pos 6341
    doc 10
      freq 3
      pos 360
      pos 370
      pos 12384
    doc 11
      freq 5
      pos 384
      pos 389
      pos 394
      pos 2245
      pos 7139
  term 3410
    doc 0
      freq 2
      pos 220
      pos 17192
  term 3411
    doc 0
      freq 1
      pos 17036
  term 3413415
    doc 11
      freq 1
      pos 8159
  term 341518
    doc 11
      freq 1
      pos 5943
  term 34525
    doc 11
      freq 2
      pos 6775
      pos 6867
  term 34kqjdjiysx6vppv26x9m7s0oydtksgs3
    doc 10
      freq 1
      pos 6234
  term 35
    doc 0
      freq 2
      pos 6422
      pos 6431
    doc 5
      freq 1
      pos 4284
    doc 10
      freq 2
      pos 376
      pos 12531
    doc 11
      freq 6
      pos 399
      pos 405
      pos 4021
      pos 4144
      pos 7267
      pos 8490
  term 350
    doc 0
      freq 1
      pos 2806
  term 3500
    doc 3
      freq 1
      pos 4874
  term 3501
    doc 16
      freq 2
      pos 12
      pos 2532
  term 3502
    doc 16
      freq 2
      pos 13
      pos 2556
  term 3513
    doc 4
      freq 1
      pos 5343
  term 352
    doc 6
      freq 1
      pos 3213
  term 353494
    doc 11
      freq 1
      pos 6982
  term 3548
    doc 10
      freq 2
      pos 5533
      pos 13223
  term 3550
    doc 6
      freq 1
      pos 3083
  term 3575
    doc 2
      freq 1
      pos 3132
  term 3579
    doc 2
      freq 1
      pos 3155
  term 3580
    doc 2
      freq 1
      pos 3182
  term 3596
    doc 12
      freq 1
      pos 7277
  term 36
    doc 0
      freq 1
      pos 6651
    doc 10
      freq 1
      pos 12695
    doc 11
      freq 3
      pos 412
      pos 421
      pos 7545
  term 3600
    doc 10
      freq 2
      pos 8519
      pos 8559
    doc 11
      freq 1
      pos 4853
    doc 18
      freq 5
      pos 1009
      pos 1017
      pos 1132
      pos 1452
      pos 1522
  term 3611
    doc 6
      freq 2
      pos 98
      pos 3059
  term 3621
    doc 2
      freq 1
      pos 3195
  term 363
    doc 10
      freq 1
      pos 13421
  term 3635
    doc 2
      freq 1
      pos 3224
  term 3636
    doc 2
      freq 1
      pos 3242
  term 3637
    doc 2
      freq 1
      pos 3260
  term 3646
    doc 12
      freq 1
      pos 7295
  term 36893488147419103232
    doc 11
      freq 1
      pos 4922
  term 37
    doc 0
      freq 1
      pos 6905
    doc 4
      freq 1
      pos 5323
    doc 10
      freq 1
      pos 12830
    doc 11
      freq 3
      pos 429
      pos 435
      pos 7779
  term 3704
    doc 12
      freq 1
      pos 7541
  term 3711
    doc 5
      freq 1
      pos 4373
  term 3736
    doc 12
      freq 1
      pos 7311
    doc 15
      freq 1
      pos 3975
  term 3748
    doc 2
      freq 1
      pos 3280
  term 3761
    doc 10
      freq 1
      pos 13359
  term 3775
    doc 9
      freq 1
      pos 1662
  term 3784
    doc 0
      freq 2
      pos 1791
      pos 1823
  term 3787
    doc 0
      freq 1
      pos 1874
  term 37uhmiqrkiljci4
    doc 10
      freq 1
      pos 12464
  term 38
    doc 0
      freq 1
      pos 7084
    doc 10
      freq 2
      pos 381
      pos 13080
    doc 11
      freq 3
      pos 440
      pos 445
      pos 8026
  term 3830
    doc 5
      freq 1
      pos 4179
  term 384
    doc 11
      freq 2
      pos 7388
      pos 7519
  term 385759045
    doc 16
      freq 10
      pos 1783
      pos 1802
      pos 1811
      pos 1830
      pos 2063
      pos 2072
      pos 2092
      pos 2164
      pos 2183
      pos 2192
  term 38678
    doc 15
      freq 1
      pos 4057
  term 3875
    doc 10
      freq 1
      pos 12756
  term 3879
    doc 12
      freq 1
      pos 7325
  term 3882340
    doc 11
      freq 1
      pos 2885
  term 3893
    doc 10
      freq 1
      pos 13181
  term 39
    doc 0
      freq 1
      pos 7248
    doc 10
      freq 4
      pos 383
      pos 386
      pos 389
      pos 13330
    doc 11
      freq 2
      pos 454
      pos 8223
    doc 14
      freq 1
      pos 4489
  term 3901
    doc 12
      freq 1
      pos 7342
  term 390skdjuw
    doc 11
      freq 1
      pos 1488
  term 3916
    doc 3
      freq 1
      pos 4586
  term 39203ndfvkjdasfkq3w4otrq0adsfdfnavd
    doc 11
      freq 1
      pos 2379
  term 3923239
    doc 11
      freq 2
      pos 6470
      pos 6633
  term 39234
    doc 11
      freq 1
      pos 4481
  term 3923423
    doc 11
      freq 2
      pos 7396
      pos 7527
  term 39234321
    doc 11
      freq 1
      pos 8618
  term 3923942
    doc 11
      freq 1
      pos 8335
  term 39291
    doc 11
      freq 1
      pos 5324
  term 3931
    doc 3
      freq 1
      pos 4729
  term 3932
    doc 6
      freq 1
      pos 171
  term 3966
    doc 10
      freq 2
      pos 7465
      pos 13322
  term 3972
    doc 12
      freq 1
      pos 7552
  term 3978
    doc 4
      freq 3
      pos 4997
      pos 5287
      pos 5297
  term 3985
    doc 1
      freq 1
      pos 9162
    doc 3
      freq 2
      pos 442
      pos 4529
  term 3986
    doc 11
      freq 1
      pos 9692
  term 399
    doc 11
      freq 1
      pos 9019
  term 39ansfi3
    doc 11
      freq 2
      pos 4150
      pos 6988
  term 3auser
    doc 11
      freq 1
      pos 2196
  term 3bp
    doc 11
      freq 1
      pos 10360
  term 3btful0qknl789ejjj91
    doc 11
      freq 1
      pos 10398
  term 3com
    doc 11
      freq 1
      pos 9611
  term 3csip:example.com
    doc 11
      freq 1
      pos 5932
  term 3csip:sip.example.com
    doc 11
      freq 2
      pos 6378
      pos 8948
  term 3cxjcuvb
    doc 10
      freq 1
      pos 12603
  term 3d9485ad0c49859b
    doc 11
      freq 1
      pos 3824
  term 3e
    doc 11
      freq 3
      pos 5933
      pos 6379
      pos 8949
  term 3ghsd41
    doc 11
      freq 1
      pos 8613
  term 3gpp
    doc 10
      freq 1
      pos 2889
    doc 12
      freq 1
      pos 7601
  term 3hn5r85oxxhcjpz800xvtxckn
    doc 11
      freq 1
      pos 10005
  term 3j6
    doc 11
      freq 1
      pos 10246
  term 3jkbdnqp
    doc 11
      freq 1
      pos 10159
  term 3jn
    doc 11
      freq 1
      pos 10294
  term 3jvpqmj17kx6zzwsm37ycny1bnbl3jt
    doc 11
      freq 1
      pos 10085
  term 3rd
    doc 9
      freq 1
      pos 1687
  term 3rx5kkiiibvvxbxs
    doc 11
      freq 1
      pos 9971
  term 3smrvivq9iqjoxaiu1
    doc 10
      freq 1
      pos 12519
  term 3w
    doc 11
      freq 1
      pos 10415
  term 3way
    doc 0
      freq 4
      pos 6204
      pos 6233
      pos 9016
      pos 9034
  term 3xc04rq9ipk1jgxe6xitvaw1yuvxc5k
    doc 11
      freq 1
      pos 9880
  term 3xfe
    doc 11
      freq 1
      pos 5462
  term 3xgd
    doc 11
      freq 1
      pos 9961
  term 4
    doc 0
      freq 36
      pos 154
      pos 820
      pos 1000
      pos 1076
      pos 1237
      pos 1320
      pos 1654
      pos 1722
      pos 1820
      pos 2524
      pos 3586
      pos 3920
      pos 4432
      pos 4632
      pos 4959
      pos 5716
      pos 5729
      pos 6496
      pos 7440
      pos 8003
      pos 8549
      pos 8976
      pos 9072
      pos 9097
      pos 9156
      pos 9851
      pos 10229
      pos 10242
      pos 11274
      pos 11660
      pos 11894
      pos 12232
      pos 12408
      pos 12651
      pos 13069
      pos 15619
    doc 1
      freq 30
      pos 227
      pos 1063
      pos 1974
      pos 2458
      pos 2468
      pos 2478
      pos 3644
      pos 3654
      pos 3664
      pos 4006
      pos 4016
      pos 4026
      pos 4082
      pos 4092
      pos 4102
      pos 5072
      pos 5082
      pos 5092
      pos 5113
      pos 5140
      pos 5241
      pos 5251
      pos 5261
      pos 5703
      pos 5713
      pos 5723
      pos 6038
      pos 6048
      pos 6058
      pos 9242
    doc 2
      freq 5
      pos 137
      pos 141
      pos 162
      pos 1467
      pos 3451
    doc 3
      freq 17
      pos 191
      pos 758
      pos 1687
      pos 3639
      pos 3649
      pos 3659
      pos 3680
      pos 5095
      pos 5106
      pos 5208
      pos 5682
      pos 5731
      pos 5740
      pos 5749
      pos 5750
      pos 5759
      pos 5770
    doc 4
      freq 34
      pos 207
      pos 594
      pos 604
      pos 614
      pos 782
      pos 982
      pos 995
      pos 1009
      pos 1728
      pos 2100
      pos 2110
      pos 2120
      pos 2188
      pos 2569
      pos 2766
      pos 2776
      pos 2786
      pos 3011
      pos 3021
      pos 3031
      pos 3247
      pos 3257
      pos 3267
      pos 3313
      pos 3480
      pos 3538
      pos 3554
      pos 3564
      pos 3574
      pos 3725
      pos 3735
      pos 3745
      pos 4351
      pos 6007
    doc 5
      freq 16
      pos 262
      pos 267
      pos 268
      pos 1143
      pos 1332
      pos 1481
      pos 1580
      pos 1590
      pos 1600
      pos 1802
      pos 1812
      pos 1822
      pos 1935
      pos 2617
      pos 2627
      pos 2637
    doc 6
      freq 2
      pos 1610
      pos 2685
    doc 7
      freq 6
      pos 133
      pos 135
      pos 1172
      pos 1300
      pos 1564
      pos 2715
    doc 8
      freq 16
      pos 136
      pos 164
      pos 1013
      pos 1020
      pos 1039
      pos 1047
      pos 1052
      pos 1066
      pos 1073
      pos 1078
      pos 1084
      pos 1091
      pos 1123
      pos 1306
      pos 1533
      pos 1676
    doc 9
      freq 8
      pos 132
      pos 135
      pos 524
      pos 530
      pos 1008
      pos 1097
      pos 1369
      pos 1703
    doc 10
      freq 8
      pos 190
      pos 1249
      pos 1773
      pos 3299
      pos 4245
      pos 10482
      pos 12787
      pos 13151
    doc 11
      freq 6
      pos 109
      pos 115
      pos 531
      pos 1044
      pos 9308
      pos 10083
    doc 12
      freq 8
      pos 167
      pos 175
      pos 183
      pos 245
      pos 1220
      pos 1951
      pos 8260
      pos 8274
    doc 13
      freq 13
      pos 148
      pos 160
      pos 458
      pos 1137
      pos 2001
      pos 3822
      pos 4069
      pos 5046
      pos 5391
      pos 5871
      pos 6254
      pos 6786
      pos 6994
    doc 14
      freq 14
      pos 148
      pos 152
      pos 167
      pos 806
      pos 1064
      pos 1218
      pos 1242
      pos 1281
      pos 1329
      pos 1341
      pos 1506
      pos 1716
      pos 1760
      pos 2833
    doc 15
      freq 9
      pos 214
      pos 219
      pos 254
      pos 362
      pos 553
      pos 1022
      pos 1759
      pos 2314
      pos 3937
    doc 16
      freq 8
      pos 1080
      pos 1211
      pos 1226
      pos 1312
      pos 1336
      pos 1384
      pos 2258
      pos 2559
    doc 17
      freq 6
      pos 849
      pos 882
      pos 1051
      pos 1942
      pos 2099
      pos 2276
    doc 18
      freq 7
      pos 167
      pos 171
      pos 410
      pos 1202
      pos 1383
      pos 1901
      pos 2126
    skipList 
      level 0
        skipDoc 7
        skipDocFP 152822
        impacts 
          impact 
            freq 6
            norm 100
          impact 
            freq 16
            norm 104
          impact 
            freq 17
            norm 107
          impact 
            freq 34
            norm 108
          impact 
            freq 36
            norm 120
        impactsEnd 
        skipDoc 15
        skipDocFP 155191
        impacts 
          impact 
            freq 8
            norm 95
          impact 
            freq 16
            norm 97
        impactsEnd 
  term 4.1
    doc 1
      freq 2
      pos 235
      pos 1981
    doc 3
      freq 2
      pos 199
      pos 1694
    doc 4
      freq 3
      pos 212
      pos 810
      pos 3542
    doc 5
      freq 3
      pos 274
      pos 1539
      pos 3728
    doc 12
      freq 2
      pos 253
      pos 1986
    doc 13
      freq 2
      pos 166
      pos 2006
    doc 14
      freq 2
      pos 170
      pos 1762
    doc 15
      freq 2
      pos 258
      pos 1824
    doc 16
      freq 1
      pos 1247
    skipList 
      level 0
        skipDoc 15
        skipDocFP 157583
        impacts 
          impact 
            freq 3
            norm 104
        impactsEnd 
  term 4.1.1
    doc 13
      freq 2
      pos 172
      pos 2011
    doc 18
      freq 1
      pos 684
  term 4.1.2
    doc 13
      freq 2
      pos 180
      pos 2427
    doc 14
      freq 1
      pos 1840
  term 4.1.3
    doc 13
      freq 2
      pos 188
      pos 2572
  term 4.2
    doc 3
      freq 2
      pos 204
      pos 1842
    doc 4
      freq 5
      pos 217
      pos 816
      pos 1712
      pos 3713
      pos 5779
    doc 5
      freq 4
      pos 280
      pos 1863
      pos 3951
      pos 3974
    doc 12
      freq 3
      pos 263
      pos 2142
      pos 2285
    doc 13
      freq 2
      pos 196
      pos 2728
    doc 14
      freq 2
      pos 175
      pos 1878
    doc 15
      freq 2
      pos 263
      pos 2250
    doc 16
      freq 1
      pos 1320
    skipList 
      level 0
        skipDoc 16
        skipDocFP 158524
        impacts 
          impact 
            freq 1
            norm 99
          impact 
            freq 4
            norm 104
          impact 
            freq 5
            norm 108
        impactsEnd 
  term 4.2.1
    doc 12
      freq 1
      pos 8228
    doc 13
      freq 2
      pos 202
      pos 2868
  term 4.2.2
    doc 13
      freq 2
      pos 209
      pos 3052
  term 4.2.3
    doc 13
      freq 2
      pos 217
      pos 3192
  term 4.2.4
    doc 13
      freq 2
      pos 221
      pos 3234
  term 4.2.5
    doc 13
      freq 2
      pos 225
      pos 3310
  term 4.2.6
    doc 13
      freq 2
      pos 229
      pos 3482
  term 4.3
    doc 3
      freq 2
      pos 209
      pos 1927
    doc 5
      freq 5
      pos 284
      pos 1107
      pos 1164
      pos 2065
      pos 2128
    doc 12
      freq 5
      pos 275
      pos 2145
      pos 2468
      pos 2512
      pos 6750
    doc 14
      freq 3
      pos 179
      pos 2004
      pos 2289
    doc 15
      freq 2
      pos 268
      pos 2791
  term 4.4
    doc 3
      freq 2
      pos 218
      pos 2125
    doc 5
      freq 3
      pos 288
      pos 2559
      pos 3761
    doc 12
      freq 3
      pos 285
      pos 2791
      pos 8386
    doc 14
      freq 3
      pos 184
      pos 2181
      pos 2222
    doc 15
      freq 2
      pos 277
      pos 3050
  term 4.4.1
    doc 3
      freq 2
      pos 222
      pos 2324
    doc 12
      freq 2
      pos 296
      pos 2894
  term 4.4.2
    doc 3
      freq 2
      pos 229
      pos 2831
    doc 12
      freq 2
      pos 303
      pos 3066
  term 4.4.3
    doc 3
      freq 3
      pos 238
      pos 2907
      pos 3470
  term 4.4.4
    doc 3
      freq 2
      pos 242
      pos 3018
  term 4.4.5
    doc 3
      freq 2
      pos 247
      pos 3141
  term 4.5
    doc 3
      freq 2
      pos 254
      pos 3215
    doc 4
      freq 1
      pos 3192
    doc 12
      freq 2
      pos 310
      pos 3159
    doc 14
      freq 2
      pos 189
      pos 2344
  term 4.5.1
    doc 14
      freq 2
      pos 193
      pos 2347
  term 4.5.2
    doc 14
      freq 2
      pos 202
      pos 2501
  term 4.6
    doc 3
      freq 3
      pos 257
      pos 2156
      pos 3260
  term 4.7
    doc 3
      freq 4
      pos 262
      pos 1684
      pos 3782
      pos 5430
  term 40
    doc 0
      freq 3
      pos 7349
      pos 7923
      pos 7960
    doc 4
      freq 1
      pos 3489
    doc 6
      freq 1
      pos 1391
    doc 10
      freq 1
      pos 13459
    doc 11
      freq 4
      pos 460
      pos 471
      pos 7886
      pos 8455
    doc 14
      freq 1
      pos 4467
  term 400
    doc 1
      freq 1
      pos 9515
    doc 3
      freq 2
      pos 4806
      pos 5880
    doc 7
      freq 13
      pos 740
      pos 917
      pos 931
      pos 935
      pos 960
      pos 1018
      pos 1198
      pos 2084
      pos 2381
      pos 2395
      pos 2399
      pos 2404
      pos 2558
    doc 8
      freq 1
      pos 2139
    doc 11
      freq 17
      pos 4264
      pos 4384
      pos 4800
      pos 5107
      pos 5274
      pos 5425
      pos 5871
      pos 6309
      pos 6418
      pos 6530
      pos 6757
      pos 6834
      pos 7066
      pos 7200
      pos 7612
      pos 8115
      pos 9044
  term 4001
    doc 0
      freq 1
      pos 17125
  term 401
    doc 11
      freq 1
      pos 7992
  term 4017
    doc 2
      freq 1
      pos 3301
  term 4025
    doc 12
      freq 1
      pos 7568
  term 4026
    doc 3
      freq 1
      pos 4710
  term 403
    doc 10
      freq 1
      pos 3093
  term 4033
    doc 18
      freq 1
      pos 2077
  term 4034
    doc 14
      freq 1
      pos 5448
    doc 18
      freq 6
      pos 13
      pos 115
      pos 674
      pos 687
      pos 1210
      pos 2100
  term 4035
    doc 18
      freq 3
      pos 12
      pos 1174
      pos 2123
  term 4038
    doc 12
      freq 1
      pos 7365
  term 404
    doc 11
      freq 2
      pos 1874
      pos 7492
  term 405
    doc 11
      freq 1
      pos 8015
  term 4052
    doc 2
      freq 1
      pos 2245
  term 4053
    doc 2
      freq 1
      pos 2269
  term 406
    doc 11
      freq 1
      pos 9013
  term 407
    doc 10
      freq 3
      pos 2591
      pos 6418
      pos 7022
  term 4074
    doc 12
      freq 1
      pos 7383
  term 408
    doc 4
      freq 1
      pos 6087
    doc 10
      freq 1
      pos 13448
  term 4082
    doc 5
      freq 1
      pos 4207
  term 4086
    doc 9
      freq 3
      pos 814
      pos 1079
      pos 1700
  term 4095
    doc 3
      freq 2
      pos 5074
      pos 5092
  term 4096
    doc 8
      freq 1
      pos 537
  term 4097
    doc 8
      freq 1
      pos 555
  term 40b0rjtznutsnuho1uu1bsfggbdoiyi6pu9
    doc 11
      freq 1
      pos 10115
  term 40example.com
    doc 11
      freq 1
      pos 2197
  term 40example.net
    doc 11
      freq 1
      pos 3511
  term 41
    doc 0
      freq 1
      pos 7511
    doc 7
      freq 1
      pos 2911
    doc 10
      freq 1
      pos 13790
    doc 11
      freq 3
      pos 477
      pos 2088
      pos 8639
  term 4107
    doc 9
      freq 3
      pos 523
      pos 1096
      pos 1717
  term 4118
    doc 2
      freq 1
      pos 3324
  term 4137
    doc 2
      freq 1
      pos 3348
  term 415
    doc 11
      freq 1
      pos 7838
  term 416
    doc 11
      freq 2
      pos 7314
      pos 7475
  term 417574686f7269747902080195007102
    doc 11
      freq 1
      pos 3902
  term 4181
    doc 2
      freq 1
      pos 3366
  term 4188
    doc 2
      freq 1
      pos 3382
  term 4192
    doc 12
      freq 1
      pos 7405
  term 4193
    doc 12
      freq 1
      pos 7420
  term 419399e1.6000505
    doc 16
      freq 2
      pos 1977
      pos 2345
  term 41xc
    doc 11
      freq 1
      pos 10096
  term 42
    doc 0
      freq 2
      pos 7676
      pos 8031
    doc 10
      freq 1
      pos 12704
    doc 11
      freq 3
      pos 485
      pos 506
      pos 8858
    doc 16
      freq 5
      pos 1789
      pos 1817
      pos 2170
      pos 2406
      pos 2425
  term 420
    doc 11
      freq 1
      pos 7699
  term 4203
    doc 4
      freq 1
      pos 5418
  term 4213
    doc 12
      freq 1
      pos 7586
  term 4215
    doc 12
      freq 1
      pos 7604
  term 4226
    doc 9
      freq 1
      pos 1759
  term 4234
    doc 10
      freq 1
      pos 13197
    doc 16
      freq 1
      pos 2618
  term 424
    doc 11
      freq 1
      pos 2855
  term 428
    doc 10
      freq 4
      pos 315
      pos 3889
      pos 11549
      pos 11629
  term 4284
    doc 2
      freq 1
      pos 2320
  term 4291
    doc 12
      freq 1
      pos 7435
  term 4294967295
    doc 0
      freq 6
      pos 8914
      pos 9499
      pos 9684
      pos 10074
      pos 11248
      pos 12127
  term 4294967301
    doc 11
      freq 1
      pos 6965
  term 43
    doc 0
      freq 6
      pos 7815
      pos 8489
      pos 8661
      pos 8706
      pos 8751
      pos 8791
    doc 3
      freq 1
      pos 2943
    doc 11
      freq 3
      pos 514
      pos 6618
      pos 8957
  term 4301
    doc 4
      freq 1
      pos 5435
  term 4302
    doc 4
      freq 1
      pos 5390
  term 4315
    doc 16
      freq 1
      pos 2602
  term 43251j3j324
    doc 11
      freq 1
      pos 3340
  term 4328
    doc 2
      freq 1
      pos 2872
  term 433423
    doc 11
      freq 1
      pos 6457
  term 4339
    doc 12
      freq 1
      pos 7451
  term 436
    doc 10
      freq 4
      pos 323
      pos 4057
      pos 11637
      pos 11724
  term 4361
    doc 15
      freq 1
      pos 3997
  term 4363
    doc 2
      freq 1
      pos 3407
  term 437
    doc 10
      freq 4
      pos 331
      pos 4147
      pos 11732
      pos 11825
  term 438
    doc 10
      freq 4
      pos 338
      pos 4236
      pos 11844
      pos 11919
  term 4380
    doc 12
      freq 1
      pos 7621
  term 4383
    doc 5
      freq 1
      pos 4235
  term 4385
    doc 3
      freq 1
      pos 4333
    doc 8
      freq 1
      pos 2124
  term 43dqox2sndnyh
    doc 10
      freq 1
      pos 6213
  term 44
    doc 0
      freq 1
      pos 7949
    doc 11
      freq 5
      pos 519
      pos 523
      pos 530
      pos 3845
      pos 9202
    doc 14
      freq 2
      pos 5520
      pos 5537
    doc 16
      freq 3
      pos 1834
      pos 2078
      pos 2442
  term 443
    doc 11
      freq 1
      pos 7890
  term 4435
    doc 13
      freq 1
      pos 6877
  term 4441
    doc 2
      freq 22
      pos 9
      pos 196
      pos 625
      pos 1075
      pos 1469
      pos 1844
      pos 2217
      pos 2454
      pos 2698
      pos 2947
      pos 3203
      pos 3444
      pos 3487
      pos 3870
      pos 4254
      pos 4662
      pos 5023
      pos 5419
      pos 5824
      pos 6217
      pos 6331
      pos 6394
  term 4442
    doc 5
      freq 18
      pos 8
      pos 249
      pos 352
      pos 788
      pos 1145
      pos 1476
      pos 1743
      pos 2046
      pos 2357
      pos 2554
      pos 2735
      pos 3049
      pos 3359
      pos 3660
      pos 3912
      pos 4112
      pos 4348
      pos 4433
  term 4443
    doc 4
      freq 24
      pos 8
      pos 141
      pos 422
      pos 742
      pos 1011
      pos 1368
      pos 1755
      pos 2077
      pos 2314
      pos 2718
      pos 2964
      pos 3201
      pos 3437
      pos 3627
      pos 3799
      pos 4089
      pos 4499
      pos 4885
      pos 5156
      pos 5401
      pos 5531
      pos 5816
      pos 6035
      pos 6101
  term 4444
    doc 0
      freq 105
      pos 9
      pos 186
      pos 487
      pos 661
      pos 822
      pos 994
      pos 1203
      pos 1225
      pos 1246
      pos 1401
      pos 1613
      pos 1779
      pos 1920
      pos 2096
      pos 2328
      pos 2538
      pos 2719
      pos 2898
      pos 3086
      pos 3247
      pos 3458
      pos 3670
      pos 3805
      pos 4016
      pos 4201
      pos 4404
      pos 4547
      pos 4704
      pos 4820
      pos 5042
      pos 5236
      pos 5473
      pos 5587
      pos 5769
      pos 5950
      pos 6178
      pos 6343
      pos 6433
      pos 6653
      pos 6907
      pos 7086
      pos 7250
      pos 7351
      pos 7513
      pos 7678
      pos 7817
      pos 7951
      pos 8135
      pos 8330
      pos 8420
      pos 8639
      pos 8827
      pos 8927
      pos 9079
      pos 9244
      pos 9438
      pos 9594
      pos 9738
      pos 9904
      pos 10044
      pos 10170
      pos 10384
      pos 10583
      pos 10809
      pos 11021
      pos 11095
      pos 11303
      pos 11484
      pos 11642
      pos 11773
      pos 11879
      pos 12050
      pos 12177
      pos 12313
      pos 12466
      pos 12638
      pos 12786
      pos 12991
      pos 13182
      pos 13341
      pos 13541
      pos 13735
      pos 13925
      pos 14136
      pos 14323
      pos 14500
      pos 14666
      pos 14804
      pos 14924
      pos 15051
      pos 15178
      pos 15308
      pos 15419
      pos 15490
      pos 15561
      pos 15639
      pos 15723
      pos 15800
      pos 16132
      pos 16321
      pos 16473
      pos 16606
      pos 16844
      pos 17102
      pos 17217
  term 4445
    doc 6
      freq 10
      pos 8
      pos 288
      pos 741
      pos 1131
      pos 1612
      pos 2027
      pos 2341
      pos 2757
      pos 3034
      pos 3224
  term 4446
    doc 1
      freq 1
      pos 8968
    doc 3
      freq 1
      pos 4351
    doc 8
      freq 9
      pos 8
      pos 186
      pos 473
      pos 798
      pos 1125
      pos 1439
      pos 1669
      pos 1930
      pos 2153
  term 4447
    doc 1
      freq 33
      pos 9
      pos 205
      pos 428
      pos 836
      pos 1065
      pos 1373
      pos 1866
      pos 2226
      pos 2422
      pos 2696
      pos 3055
      pos 3425
      pos 3610
      pos 3907
      pos 4244
      pos 4638
      pos 5018
      pos 5297
      pos 5689
      pos 6024
      pos 6365
      pos 6760
      pos 7198
      pos 7640
      pos 7890
      pos 8238
      pos 8706
      pos 9021
      pos 9225
      pos 9332
      pos 9402
      pos 9497
      pos 9598
    doc 3
      freq 1
      pos 4381
    doc 8
      freq 1
      pos 1809
  term 4448
    doc 1
      freq 1
      pos 9118
    doc 3
      freq 24
      pos 9
      pos 168
      pos 333
      pos 580
      pos 760
      pos 1039
      pos 1425
      pos 1778
      pos 2117
      pos 2428
      pos 2823
      pos 3207
      pos 3616
      pos 4010
      pos 4298
      pos 4559
      pos 4740
      pos 4833
      pos 4937
      pos 5002
      pos 5198
      pos 5588
      pos 5789
      pos 5945
    doc 8
      freq 1
      pos 2006
  term 4449
    doc 9
      freq 7
      pos 8
      pos 231
      pos 594
      pos 935
      pos 1371
      pos 1726
      pos 1797
  term 4450
    doc 7
      freq 11
      pos 8
      pos 201
      pos 588
      pos 952
      pos 1302
      pos 1650
      pos 1824
      pos 2178
      pos 2536
      pos 2891
      pos 2938
  term 4466
    doc 16
      freq 1
      pos 2633
  term 4469
    doc 16
      freq 13
      pos 8
      pos 168
      pos 534
      pos 909
      pos 1314
      pos 1569
      pos 1688
      pos 1856
      pos 2114
      pos 2251
      pos 2513
      pos 2642
      pos 2682
  term 4470
    doc 14
      freq 1
      pos 5484
    doc 18
      freq 8
      pos 8
      pos 246
      pos 622
      pos 1030
      pos 1385
      pos 1812
      pos 2152
      pos 2195
  term 4471
    doc 14
      freq 23
      pos 8
      pos 216
      pos 559
      pos 843
      pos 1220
      pos 1549
      pos 1870
      pos 2160
      pos 2551
      pos 2905
      pos 3258
      pos 3542
      pos 3840
      pos 4136
      pos 4222
      pos 4287
      pos 4409
      pos 4503
      pos 4585
      pos 4963
      pos 5191
      pos 5457
      pos 5550
  term 4472
    doc 12
      freq 29
      pos 8
      pos 238
      pos 500
      pos 864
      pos 1222
      pos 1559
      pos 1944
      pos 2278
      pos 2649
      pos 3021
      pos 3385
      pos 3814
      pos 4196
      pos 4561
      pos 5012
      pos 5421
      pos 5857
      pos 6247
      pos 6640
      pos 6985
      pos 7232
      pos 7461
      pos 7705
      pos 7885
      pos 8238
      pos 8635
      pos 9047
      pos 9419
      pos 9470
  term 4473
    doc 13
      freq 23
      pos 8
      pos 123
      pos 353
      pos 757
      pos 1139
      pos 1460
      pos 1819
      pos 2171
      pos 2563
      pos 2934
      pos 3301
      pos 3662
      pos 3963
      pos 4298
      pos 4673
      pos 5018
      pos 5380
      pos 5730
      pos 6009
      pos 6331
      pos 6653
      pos 6943
      pos 7083
  term 4474
    doc 10
      freq 41
      pos 8
      pos 173
      pos 397
      pos 788
      pos 1251
      pos 1702
      pos 2089
      pos 2515
      pos 2970
      pos 3374
      pos 3786
      pos 4185
      pos 4596
      pos 4940
      pos 5400
      pos 5765
      pos 6055
      pos 6273
      pos 6526
      pos 6781
      pos 6967
      pos 7271
      pos 7601
      pos 8033
      pos 8467
      pos 8987
      pos 9477
      pos 9942
      pos 10332
      pos 10788
      pos 11205
      pos 11543
      pos 11838
      pos 12095
      pos 12386
      pos 12533
      pos 12697
      pos 12832
      pos 13082
      pos 13332
      pos 13461
  term 4475
    doc 10
      freq 2
      pos 12163
      pos 13400
    doc 11
      freq 53
      pos 9
      pos 190
      pos 493
      pos 820
      pos 1046
      pos 1253
      pos 1439
      pos 1573
      pos 1897
      pos 2111
      pos 2291
      pos 2543
      pos 2784
      pos 3052
      pos 3319
      pos 3442
      pos 3687
      pos 3883
      pos 3984
      pos 4170
      pos 4410
      pos 4653
      pos 4891
      pos 5069
      pos 5236
      pos 5393
      pos 5541
      pos 5701
      pos 5833
      pos 6021
      pos 6245
      pos 6481
      pos 6717
      pos 6931
      pos 7141
      pos 7269
      pos 7547
      pos 7781
      pos 8028
      pos 8225
      pos 8457
      pos 8641
      pos 8860
      pos 8959
      pos 9204
      pos 9414
      pos 9721
      pos 9859
      pos 10025
      pos 10215
      pos 10424
      pos 10517
      pos 10620
  term 4476
    doc 17
      freq 11
      pos 8
      pos 156
      pos 515
      pos 815
      pos 1053
      pos 1399
      pos 1848
      pos 2113
      pos 2151
      pos 2320
      pos 2406
  term 4477
    doc 15
      freq 14
      pos 8
      pos 193
      pos 304
      pos 634
      pos 1024
      pos 1392
      pos 1752
      pos 2147
      pos 2593
      pos 3005
      pos 3406
      pos 3801
      pos 4007
      pos 4070
  term 4478
    doc 16
      freq 1
      pos 2668
  term 44dhwg2w
    doc 11
      freq 1
      pos 10047
  term 45
    doc 0
      freq 4
      pos 6828
      pos 6922
      pos 6969
      pos 8133
    doc 11
      freq 5
      pos 534
      pos 2470
      pos 2561
      pos 2566
      pos 9412
    doc 14
      freq 1
      pos 3528
    doc 16
      freq 1
      pos 2093
  term 450
    doc 11
      freq 1
      pos 10593
  term 45r
    doc 11
      freq 2
      pos 2555
      pos 2587
  term 46
    doc 0
      freq 2
      pos 5818
      pos 8328
    doc 5
      freq 1
      pos 4285
    doc 11
      freq 3
      pos 537
      pos 541
      pos 9719
  term 47
    doc 0
      freq 1
      pos 8418
    doc 11
      freq 2
      pos 551
      pos 9857
    doc 12
      freq 1
      pos 9448
    doc 14
      freq 5
      pos 4185
      pos 4207
      pos 4273
      pos 4550
      pos 4571
    doc 18
      freq 1
      pos 2183
  term 47ist
    doc 11
      freq 2
      pos 2554
      pos 2586
  term 48
    doc 0
      freq 1
      pos 8637
    doc 11
      freq 2
      pos 557
      pos 10023
    doc 12
      freq 3
      pos 1419
      pos 5312
      pos 5333
    doc 14
      freq 1
      pos 4252
  term 483
    doc 11
      freq 1
      pos 8578
  term 4886f70d010702a08201433082013f02
    doc 11
      freq 1
      pos 3892
  term 49
    doc 0
      freq 1
      pos 8825
    doc 11
      freq 1
      pos 10213
    doc 12
      freq 1
      pos 7166
    doc 14
      freq 5
      pos 3209
      pos 3815
      pos 4122
      pos 4377
      pos 4862
  term 49.0001
    doc 0
      freq 1
      pos 3200
  term 49172
    doc 10
      freq 3
      pos 6396
      pos 6533
      pos 6696
  term 49217
    doc 11
      freq 20
      pos 1551
      pos 2269
      pos 3187
      pos 3420
      pos 4063
      pos 4328
      pos 4509
      pos 4723
      pos 5214
      pos 5371
      pos 5519
      pos 5679
      pos 5999
      pos 6223
      pos 6909
      pos 7247
      pos 8203
      pos 8532
      pos 9127
      pos 9304
  term 49j9
    doc 10
      freq 1
      pos 12599
  term 4ctdm
    doc 11
      freq 1
      pos 10285
  term 4dade06d0bdb11e
    doc 11
      freq 1
      pos 3786
  term 4f3x4
    doc 10
      freq 1
      pos 12707
  term 4kyjvlqdseflgkslf9nwsb
    doc 11
      freq 1
      pos 10448
  term 4oopxo8hamqxm80cqb
    doc 10
      freq 1
      pos 6235
  term 4p5npgnkwtcxwprbn3pwkyjuy4ot7e4vjchcbuy7txnof
    doc 11
      freq 1
      pos 10145
  term 4psiiy8f
    doc 11
      freq 1
      pos 9966
  term 4rev1
    doc 16
      freq 1
      pos 2530
  term 4snhtzix7vl
    doc 11
      freq 1
      pos 10182
  term 4trqmx3pwwgkukpf3vvsbe7ukkzajt
    doc 11
      freq 1
      pos 10002
  term 4vddi3rfm9sdedchoel
    doc 11
      freq 1
      pos 10482
  term 4x0
    doc 11
      freq 1
      pos 10336
  term 4xqmseg9pz
    doc 11
      freq 1
      pos 10321
  term 4xx
    doc 10
      freq 1
      pos 4510
  term 5
    doc 0
      freq 39
      pos 153
      pos 161
      pos 992
      pos 1329
      pos 1871
      pos 2605
      pos 3950
      pos 4094
      pos 5016
      pos 5731
      pos 5785
      pos 6606
      pos 7009
      pos 7075
      pos 7077
      pos 7467
      pos 8033
      pos 8606
      pos 9116
      pos 10464
      pos 11296
      pos 11662
      pos 11916
      pos 12251
      pos 12433
      pos 12893
      pos 13147
      pos 13171
      pos 13249
      pos 13466
      pos 13564
      pos 13656
      pos 13758
      pos 13831
      pos 13903
      pos 14043
      pos 14172
      pos 15666
      pos 15806
    doc 1
      freq 30
      pos 221
      pos 226
      pos 241
      pos 1371
      pos 2050
      pos 2459
      pos 2469
      pos 2479
      pos 3645
      pos 3655
      pos 3665
      pos 4007
      pos 4017
      pos 4027
      pos 4083
      pos 4093
      pos 4103
      pos 5073
      pos 5083
      pos 5093
      pos 5242
      pos 5252
      pos 5262
      pos 5704
      pos 5714
      pos 5724
      pos 6039
      pos 6049
      pos 6059
      pos 8420
    doc 2
      freq 4
      pos 145
      pos 149
      pos 1842
      pos 2783
    doc 3
      freq 13
      pos 266
      pos 1037
      pos 3640
      pos 3650
      pos 3660
      pos 4065
      pos 5683
      pos 5742
      pos 5751
      pos 5760
      pos 5761
      pos 5771
      pos 5776
    doc 4
      freq 34
      pos 170
      pos 175
      pos 180
      pos 222
      pos 595
      pos 605
      pos 615
      pos 1366
      pos 1763
      pos 2101
      pos 2111
      pos 2121
      pos 2191
      pos 2629
      pos 2675
      pos 2767
      pos 2777
      pos 2787
      pos 3012
      pos 3022
      pos 3032
      pos 3248
      pos 3258
      pos 3268
      pos 3555
      pos 3565
      pos 3575
      pos 3726
      pos 3736
      pos 3746
      pos 4019
      pos 4393
      pos 5107
      pos 5221
    doc 5
      freq 15
      pos 298
      pos 1359
      pos 1474
      pos 1581
      pos 1591
      pos 1601
      pos 1803
      pos 1813
      pos 1823
      pos 1943
      pos 1984
      pos 2618
      pos 2628
      pos 2638
      pos 2740
    doc 6
      freq 2
      pos 2025
      pos 2766
    doc 7
      freq 7
      pos 136
      pos 139
      pos 1425
      pos 1648
      pos 2796
      pos 2814
      pos 2828
    doc 8
      freq 7
      pos 140
      pos 146
      pos 153
      pos 168
      pos 1437
      pos 1541
      pos 1720
    doc 9
      freq 9
      pos 136
      pos 138
      pos 141
      pos 145
      pos 448
      pos 1051
      pos 1620
      pos 1724
      pos 1737
    doc 10
      freq 5
      pos 195
      pos 1700
      pos 2094
      pos 5306
      pos 13168
    doc 11
      freq 16
      pos 121
      pos 126
      pos 131
      pos 135
      pos 141
      pos 535
      pos 1251
      pos 2844
      pos 3156
      pos 4000
      pos 5472
      pos 8142
      pos 8183
      pos 8351
      pos 9083
      pos 9421
    doc 12
      freq 11
      pos 191
      pos 196
      pos 200
      pos 204
      pos 209
      pos 318
      pos 1557
      pos 1901
      pos 3217
      pos 8264
      pos 8278
    doc 13
      freq 11
      pos 151
      pos 155
      pos 237
      pos 461
      pos 1458
      pos 3619
      pos 4201
      pos 5485
      pos 5897
      pos 6267
      pos 6793
    doc 14
      freq 7
      pos 159
      pos 227
      pos 805
      pos 873
      pos 1337
      pos 1547
      pos 2884
    doc 15
      freq 10
      pos 224
      pos 228
      pos 233
      pos 239
      pos 283
      pos 409
      pos 558
      pos 1390
      pos 3225
      pos 3962
    doc 16
      freq 4
      pos 1087
      pos 1409
      pos 1567
      pos 2569
    doc 17
      freq 17
      pos 536
      pos 538
      pos 857
      pos 873
      pos 875
      pos 898
      pos 900
      pos 907
      pos 1397
      pos 1992
      pos 2180
      pos 2182
      pos 2220
      pos 2222
      pos 2245
      pos 2247
      pos 2284
    doc 18
      freq 7
      pos 172
      pos 175
      pos 379
      pos 458
      pos 506
      pos 1635
      pos 1810
    skipList 
      level 0
        skipDoc 7
        skipDocFP 178665
        impacts 
          impact 
            freq 7
            norm 100
          impact 
            freq 15
            norm 104
          impact 
            freq 34
            norm 108
          impact 
            freq 39
            norm 120
        impactsEnd 
        skipDoc 15
        skipDocFP 181015
        impacts 
          impact 
            freq 9
            norm 95
          impact 
            freq 10
            norm 104
          impact 
            freq 11
            norm 109
          impact 
            freq 16
            norm 114
        impactsEnd 
  term 5.1
    doc 1
      freq 2
      pos 244
      pos 2266
    doc 4
      freq 2
      pos 226
      pos 4022
    doc 5
      freq 2
      pos 302
      pos 2972
    doc 8
      freq 2
      pos 171
      pos 1722
    doc 10
      freq 2
      pos 200
      pos 3388
    doc 12
      freq 3
      pos 326
      pos 3247
      pos 6752
    doc 13
      freq 2
      pos 240
      pos 3621
    doc 14
      freq 3
      pos 230
      pos 2949
      pos 2952
    doc 17
      freq 1
      pos 1994
    skipList 
      level 0
        skipDoc 14
        skipDocFP 183462
        impacts 
          impact 
            freq 2
            norm 97
          impact 
            freq 3
            norm 107
        impactsEnd 
  term 5.1.1
    doc 13
      freq 2
      pos 244
      pos 3624
  term 5.1.2
    doc 13
      freq 2
      pos 253
      pos 3706
  term 5.1.3
    doc 13
      freq 2
      pos 258
      pos 3818
  term 5.2
    doc 1
      freq 3
      pos 248
      pos 2331
      pos 2386
    doc 4
      freq 4
      pos 234
      pos 4096
      pos 5775
      pos 5868
    doc 5
      freq 2
      pos 309
      pos 3160
    doc 8
      freq 2
      pos 175
      pos 1781
    doc 12
      freq 2
      pos 335
      pos 3959
    doc 13
      freq 2
      pos 261
      pos 3866
    doc 14
      freq 2
      pos 239
      pos 4144
    doc 17
      freq 1
      pos 2119
    skipList 
      level 0
        skipDoc 17
        skipDocFP 184384
        impacts 
          impact 
            freq 2
            norm 97
          impact 
            freq 4
            norm 108
        impactsEnd 
  term 5.2.1
    doc 13
      freq 2
      pos 265
      pos 3972
  term 5.2.2
    doc 13
      freq 2
      pos 268
      pos 4062
  term 5.2.3
    doc 13
      freq 3
      pos 274
      pos 4196
      pos 5649
  term 5.2.4
    doc 13
      freq 2
      pos 278
      pos 4267
  term 5.3
    doc 1
      freq 3
      pos 254
      pos 2334
      pos 2891
    doc 5
      freq 2
      pos 313
      pos 3281
    doc 12
      freq 2
      pos 344
      pos 4135
    doc 13
      freq 2
      pos 285
      pos 4372
    doc 14
      freq 2
      pos 248
      pos 4873
  term 5.3.1
    doc 0
      freq 1
      pos 1688
    doc 1
      freq 2
      pos 261
      pos 3061
  term 5.3.2
    doc 1
      freq 2
      pos 265
      pos 3616
  term 5.3.2.1
    doc 1
      freq 3
      pos 273
      pos 2304
      pos 3944
  term 5.3.2.2
    doc 1
      freq 3
      pos 278
      pos 2310
      pos 4070
  term 5.3.3
    doc 1
      freq 3
      pos 283
      pos 2373
      pos 4318
  term 5.4
    doc 1
      freq 2
      pos 287
      pos 4802
    doc 5
      freq 2
      pos 319
      pos 3403
    doc 13
      freq 2
      pos 289
      pos 4705
    doc 14
      freq 2
      pos 256
      pos 5127
  term 5.4.1
    doc 1
      freq 3
      pos 293
      pos 2385
      pos 4807
    doc 13
      freq 2
      pos 292
      pos 4707
  term 5.4.2
    doc 1
      freq 4
      pos 300
      pos 2298
      pos 2369
      pos 5024
    doc 13
      freq 2
      pos 296
      pos 5040
  term 5.4.3
    doc 1
      freq 2
      pos 305
      pos 5603
  term 5.5
    doc 1
      freq 2
      pos 311
      pos 5966
    doc 5
      freq 2
      pos 323
      pos 3558
    doc 13
      freq 2
      pos 301
      pos 5127
  term 50
    doc 0
      freq 2
      pos 2655
      pos 8925
    doc 11
      freq 3
      pos 2852
      pos 3143
      pos 10422
    doc 12
      freq 2
      pos 8944
      pos 8945
  term 500
    doc 6
      freq 1
      pos 3203
    doc 7
      freq 3
      pos 717
      pos 2025
      pos 2041
  term 5000
    doc 11
      freq 1
      pos 10578
  term 501
    doc 11
      freq 4
      pos 1879
      pos 2535
      pos 6830
      pos 6843
  term 503
    doc 11
      freq 1
      pos 5022
  term 505
    doc 11
      freq 1
      pos 6665
  term 5050
    doc 11
      freq 1
      pos 5185
  term 5060
    doc 11
      freq 7
      pos 5486
      pos 6371
      pos 6445
      pos 6606
      pos 7665
      pos 8734
      pos 8824
  term 5070
    doc 11
      freq 2
      pos 3782
      pos 3813
  term 508
    doc 6
      freq 1
      pos 3192
  term 5080
    doc 11
      freq 1
      pos 3797
  term 509
    doc 10
      freq 2
      pos 13238
      pos 13261
    doc 17
      freq 5
      pos 450
      pos 454
      pos 2058
      pos 2123
      pos 2128
  term 51
    doc 0
      freq 2
      pos 6714
      pos 9077
    doc 10
      freq 3
      pos 7144
      pos 7243
      pos 7357
    doc 11
      freq 1
      pos 10515
    doc 15
      freq 1
      pos 4053
  term 512
    doc 0
      freq 1
      pos 1631
  term 52
    doc 0
      freq 1
      pos 9242
    doc 11
      freq 1
      pos 10618
  term 5200
    doc 3
      freq 1
      pos 4889
  term 53
    doc 0
      freq 1
      pos 9436
    doc 2
      freq 1
      pos 5781
    doc 11
      freq 1
      pos 10951
  term 54
    doc 0
      freq 1
      pos 9592
    doc 8
      freq 3
      pos 924
      pos 1249
      pos 1430
  term 541
    doc 16
      freq 1
      pos 2310
  term 55
    doc 0
      freq 1
      pos 9736
  term 553
    doc 11
      freq 1
      pos 3855
  term 555
    doc 4
      freq 1
      pos 6078
  term 55es1qdqmrvdzptl
    doc 11
      freq 1
      pos 10101
  term 55s
    doc 10
      freq 1
      pos 12555
  term 56
    doc 0
      freq 1
      pos 9902
    doc 2
      freq 1
      pos 5860
    doc 11
      freq 2
      pos 3846
      pos 9279
    doc 13
      freq 1
      pos 2442
  term 56ite
    doc 11
      freq 1
      pos 1631
  term 57
    doc 0
      freq 1
      pos 10042
    doc 16
      freq 4
      pos 1971
      pos 1986
      pos 2339
      pos 2354
  term 570
    doc 10
      freq 1
      pos 13413
  term 5775
    doc 16
      freq 1
      pos 2655
  term 58
    doc 0
      freq 7
      pos 284
      pos 289
      pos 295
      pos 10168
      pos 17055
      pos 17073
      pos 17091
    doc 4
      freq 3
      pos 320
      pos 560
      pos 1307
    doc 11
      freq 1
      pos 9825
  term 59
    doc 0
      freq 1
      pos 10382
    doc 11
      freq 2
      pos 8149
      pos 10198
  term 59381fvifh05
    doc 10
      freq 1
      pos 12738
  term 5b
    doc 16
      freq 1
      pos 1527
  term 5cs
    doc 10
      freq 1
      pos 12721
  term 5cwm
    doc 11
      freq 1
      pos 9976
  term 5d0sioeaqfuj2hnauh5ggow3pxmgcazyu
    doc 11
      freq 1
      pos 9878
  term 5efsbw1qn2xxmnp5gtblqxqupfiffbdzcet
    doc 10
      freq 1
      pos 12466
  term 5fjmb
    doc 11
      freq 1
      pos 10043
  term 5knkwm5iyjup6a4jpui5wfu
    doc 10
      freq 1
      pos 12682
  term 5ko3
    doc 10
      freq 1
      pos 12548
  term 5l
    doc 11
      freq 1
      pos 10063
  term 5lrnmn
    doc 11
      freq 1
      pos 10084
  term 5n9
    doc 10
      freq 1
      pos 12703
  term 5pd
    doc 11
      freq 1
      pos 10305
  term 5rjouud4
    doc 11
      freq 1
      pos 10146
  term 5rnpx
    doc 11
      freq 1
      pos 9936
  term 5ton9wnxjzn
    doc 10
      freq 1
      pos 12644
  term 5tryu4sehgqgkwlhv
    doc 10
      freq 1
      pos 6887
  term 5ztduomx34dx3ck8cydpc76
    doc 10
      freq 1
      pos 12498
  term 5zv2
    doc 11
      freq 1
      pos 10414
  term 6
    doc 0
      freq 29
      pos 160
      pos 165
      pos 1201
      pos 1341
      pos 1495
      pos 1513
      pos 1763
      pos 2601
      pos 2657
      pos 3981
      pos 4474
      pos 5136
      pos 5822
      pos 6716
      pos 7497
      pos 8083
      pos 8663
      pos 9142
      pos 10501
      pos 11343
      pos 11664
      pos 11940
      pos 12274
      pos 12459
      pos 13055
      pos 13273
      pos 14223
      pos 15691
      pos 15837
    doc 1
      freq 27
      pos 317
      pos 1864
      pos 2460
      pos 2470
      pos 2480
      pos 3646
      pos 3656
      pos 3666
      pos 4008
      pos 4018
      pos 4028
      pos 4084
      pos 4094
      pos 4104
      pos 5074
      pos 5084
      pos 5094
      pos 5243
      pos 5253
      pos 5263
      pos 5705
      pos 5715
      pos 5725
      pos 6040
      pos 6050
      pos 6060
      pos 6285
    doc 2
      freq 3
      pos 153
      pos 157
      pos 2215
    doc 3
      freq 12
      pos 186
      pos 190
      pos 270
      pos 1423
      pos 3641
      pos 3651
      pos 3661
      pos 4174
      pos 5684
      pos 5753
      pos 5762
      pos 5772
    doc 4
      freq 39
      pos 38
      pos 131
      pos 238
      pos 286
      pos 596
      pos 606
      pos 616
      pos 880
      pos 1753
      pos 1783
      pos 2102
      pos 2112
      pos 2122
      pos 2198
      pos 2655
      pos 2677
      pos 2768
      pos 2778
      pos 2788
      pos 3013
      pos 3023
      pos 3033
      pos 3249
      pos 3259
      pos 3269
      pos 3556
      pos 3566
      pos 3576
      pos 3727
      pos 3737
      pos 3747
      pos 4565
      pos 4741
      pos 5114
      pos 5185
      pos 5206
      pos 5243
      pos 5338
      pos 5360
    doc 5
      freq 19
      pos 273
      pos 279
      pos 327
      pos 1377
      pos 1582
      pos 1592
      pos 1602
      pos 1741
      pos 1804
      pos 1814
      pos 1824
      pos 1949
      pos 2015
      pos 2619
      pos 2629
      pos 2639
      pos 3692
      pos 4404
      pos 4418
    doc 6
      freq 2
      pos 2339
      pos 2866
    doc 7
      freq 7
      pos 140
      pos 143
      pos 147
      pos 150
      pos 154
      pos 1678
      pos 1822
    doc 8
      freq 4
      pos 157
      pos 163
      pos 1058
      pos 1667
    doc 9
      freq 5
      pos 139
      pos 149
      pos 1644
      pos 1752
      pos 1795
    doc 10
      freq 13
      pos 194
      pos 208
      pos 2087
      pos 3791
      pos 4798
      pos 5319
      pos 6238
      pos 11568
      pos 11656
      pos 11750
      pos 11863
      pos 12689
      pos 13184
    doc 11
      freq 8
      pos 538
      pos 1155
      pos 1437
      pos 6778
      pos 6870
      pos 7748
      pos 9616
      pos 10399
    doc 12
      freq 10
      pos 215
      pos 224
      pos 230
      pos 351
      pos 1942
      pos 4203
      pos 7212
      pos 7253
      pos 7275
      pos 7431
    doc 13
      freq 10
      pos 159
      pos 305
      pos 535
      pos 1817
      pos 4217
      pos 5524
      pos 5650
      pos 5923
      pos 6297
      pos 6803
    doc 14
      freq 6
      pos 166
      pos 169
      pos 174
      pos 264
      pos 1868
      pos 5274
    doc 15
      freq 9
      pos 244
      pos 249
      pos 253
      pos 286
      pos 1750
      pos 2643
      pos 3168
      pos 3808
      pos 3978
    doc 16
      freq 4
      pos 1190
      pos 1575
      pos 1686
      pos 2591
    doc 17
      freq 7
      pos 532
      pos 869
      pos 894
      pos 1846
      pos 2176
      pos 2216
      pos 2241
    doc 18
      freq 5
      pos 176
      pos 178
      pos 182
      pos 1995
      pos 2150
    skipList 
      level 0
        skipDoc 7
        skipDocFP 190730
        impacts 
          impact 
            freq 7
            norm 100
          impact 
            freq 19
            norm 104
          impact 
            freq 39
            norm 108
        impactsEnd 
        skipDoc 15
        skipDocFP 192975
        impacts 
          impact 
            freq 5
            norm 95
          impact 
            freq 9
            norm 104
          impact 
            freq 10
            norm 109
          impact 
            freq 13
            norm 116
        impactsEnd 
  term 6.1
    doc 1
      freq 3
      pos 321
      pos 2353
      pos 6288
    doc 4
      freq 2
      pos 242
      pos 4744
    doc 5
      freq 1
      pos 1635
    doc 9
      freq 2
      pos 142
      pos 1646
    doc 12
      freq 2
      pos 358
      pos 4371
    doc 13
      freq 2
      pos 309
      pos 5784
    doc 14
      freq 2
      pos 379
      pos 1906
    doc 18
      freq 2
      pos 677
      pos 1207
    skipList 
      level 0
        skipDoc 18
        skipDocFP 195043
        impacts 
          impact 
            freq 2
            norm 95
          impact 
            freq 3
            norm 113
        impactsEnd 
  term 6.1.1
    doc 5
      freq 1
      pos 1680
  term 6.10
    doc 5
      freq 1
      pos 1515
  term 6.2
    doc 1
      freq 3
      pos 332
      pos 2357
      pos 6371
    doc 4
      freq 2
      pos 253
      pos 5050
    doc 5
      freq 1
      pos 1204
    doc 9
      freq 2
      pos 146
      pos 1734
    doc 12
      freq 4
      pos 365
      pos 4407
      pos 5807
      pos 6089
    doc 13
      freq 2
      pos 315
      pos 6018
  term 6.3
    doc 1
      freq 2
      pos 344
      pos 7090
    doc 13
      freq 2
      pos 318
      pos 6135
  term 6.4
    doc 1
      freq 2
      pos 350
      pos 7362
    doc 13
      freq 2
      pos 324
      pos 6360
  term 6.4.1
    doc 1
      freq 2
      pos 354
      pos 7391
  term 6.4.2
    doc 1
      freq 2
      pos 358
      pos 7669
  term 6.5
    doc 13
      freq 2
      pos 331
      pos 6489
  term 6.6
    doc 5
      freq 1
      pos 2004
  term 60
    doc 0
      freq 2
      pos 2705
      pos 10581
    doc 11
      freq 3
      pos 2697
      pos 3636
      pos 8348
    doc 14
      freq 3
      pos 3216
      pos 3822
      pos 4955
  term 600
    doc 0
      freq 1
      pos 7098
    doc 1
      freq 1
      pos 9315
    doc 3
      freq 1
      pos 4816
    doc 11
      freq 1
      pos 10568
  term 6000
    doc 11
      freq 1
      pos 2815
  term 600000
    doc 0
      freq 1
      pos 6839
  term 61
    doc 0
      freq 1
      pos 10807
    doc 7
      freq 1
      pos 1393
  term 618
    doc 6
      freq 1
      pos 3193
  term 61dz5z
    doc 11
      freq 1
      pos 10278
  term 61lue
    doc 11
      freq 1
      pos 2243
  term 61me
    doc 11
      freq 1
      pos 2241
  term 62
    doc 0
      freq 2
      pos 11019
      pos 17034
    doc 14
      freq 1
      pos 4397
  term 625
    doc 9
      freq 2
      pos 1781
      pos 1786
  term 63
    doc 0
      freq 2
      pos 1744
      pos 11093
    doc 14
      freq 46
      pos 678
      pos 2609
      pos 3211
      pos 3213
      pos 3530
      pos 3532
      pos 3534
      pos 3817
      pos 3819
      pos 4124
      pos 4126
      pos 4128
      pos 4187
      pos 4189
      pos 4191
      pos 4210
      pos 4212
      pos 4214
      pos 4254
      pos 4256
      pos 4258
      pos 4275
      pos 4277
      pos 4279
      pos 4379
      pos 4381
      pos 4383
      pos 4399
      pos 4401
      pos 4471
      pos 4473
      pos 4475
      pos 4491
      pos 4493
      pos 4495
      pos 4552
      pos 4554
      pos 4556
      pos 4573
      pos 4575
      pos 4577
      pos 4864
      pos 4866
      pos 4868
      pos 5125
      pos 5269
    doc 18
      freq 1
      pos 1312
  term 63124
    doc 11
      freq 1
      pos 10560
  term 63bo2tjehgutvh
    doc 10
      freq 1
      pos 12472
  term 64
    doc 0
      freq 4
      pos 1969
      pos 6494
      pos 11301
      pos 12397
    doc 5
      freq 1
      pos 2375
    doc 6
      freq 1
      pos 3081
    doc 8
      freq 3
      pos 847
      pos 1173
      pos 1354
    doc 10
      freq 2
      pos 12422
      pos 12442
    doc 11
      freq 2
      pos 9829
      pos 9849
    doc 12
      freq 2
      pos 5308
      pos 5744
  term 65
    doc 0
      freq 1
      pos 11482
    doc 8
      freq 4
      pos 865
      pos 1191
      pos 1372
      pos 1571
  term 65,536
    doc 9
      freq 1
      pos 1307
  term 650
    doc 9
      freq 2
      pos 1780
      pos 1785
  term 651
    doc 16
      freq 1
      pos 2667
  term 65235
    doc 0
      freq 1
      pos 2531
  term 65535
    doc 0
      freq 7
      pos 2054
      pos 2612
      pos 2664
      pos 2807
      pos 4811
      pos 6980
      pos 9237
  term 65737420436572746966696361746520
    doc 11
      freq 1
      pos 3901
  term 65g
    doc 10
      freq 1
      pos 12706
  term 66
    doc 0
      freq 1
      pos 11640
    doc 11
      freq 2
      pos 1940
      pos 9690
  term 660
    doc 17
      freq 3
      pos 593
      pos 1998
      pos 2005
  term 66f948f0522dd2e5978e9d95aae9f2f
    doc 11
      freq 1
      pos 3905
  term 67
    doc 0
      freq 1
      pos 11771
    doc 12
      freq 1
      pos 5972
  term 678
    doc 6
      freq 1
      pos 3212
  term 68
    doc 0
      freq 1
      pos 11877
  term 680
    doc 17
      freq 1
      pos 2092
  term 6889
    doc 4
      freq 1
      pos 6089
  term 68kzjibpjv6bq0x
    doc 11
      freq 1
      pos 9918
  term 69
    doc 0
      freq 2
      pos 10372
      pos 12048
  term 692gm2l6v
    doc 11
      freq 1
      pos 9891
  term 693
    doc 17
      freq 1
      pos 2094
  term 699
    doc 11
      freq 1
      pos 6950
  term 6bl0eb5bakea636omanp0qa3
    doc 10
      freq 1
      pos 6850
  term 6c
    doc 11
      freq 1
      pos 2238
  term 6cer
    doc 11
      freq 1
      pos 2235
  term 6dvef
    doc 10
      freq 1
      pos 12556
  term 6dvru65bthjxjxozpppt1bjbharjstqevs
    doc 11
      freq 1
      pos 10235
  term 6esnol
    doc 11
      freq 1
      pos 10035
  term 6fntact
    doc 11
      freq 2
      pos 2497
      pos 2596
  term 6fpgjqozudw
    doc 10
      freq 1
      pos 6219
  term 6fr
    doc 10
      freq 1
      pos 6836
  term 6frp40l
    doc 11
      freq 1
      pos 10300
  term 6g2
    doc 11
      freq 1
      pos 10067
  term 6ho406uu2vf
    doc 10
      freq 1
      pos 12520
  term 6hvb8pqjlvyrj3q4simcaweaaaobstcbrjadbgnvhq4efgqu0z
    doc 10
      freq 1
      pos 6896
  term 6j1
    doc 11
      freq 1
      pos 10316
  term 6jgq4nrkrtlz84n2gdarclmc0jtdodfrdu
    doc 10
      freq 1
      pos 12754
  term 6jt7ctwper9uihq7bwmt2xu51ciuhpoxtu0rqannadguekwddeu1gnjz6bxxbovy
    doc 10
      freq 1
      pos 12613
  term 6k1bo5ht8xkcxs03mb1du6zdjwnqm5t7veuysarokxbjswylorb
    doc 11
      freq 1
      pos 9964
  term 6lb
    doc 14
      freq 1
      pos 5517
  term 6mib4rleh2sj6eosifpgyz9iqt3cdcgm
    doc 11
      freq 1
      pos 10378
  term 6net
    doc 15
      freq 1
      pos 3888
  term 6o7r9tsm
    doc 10
      freq 1
      pos 12669
  term 6reupc4058mvlwipboll7z
    doc 11
      freq 1
      pos 10174
  term 6rv
    doc 11
      freq 1
      pos 10402
  term 6sa0i
    doc 11
      freq 1
      pos 10434
  term 6sqvgje7jmeft49zloqxkqn4zvaxxgyvpf
    doc 11
      freq 1
      pos 10248
  term 6to4
    doc 12
      freq 7
      pos 202
      pos 1397
      pos 1399
      pos 1462
      pos 1476
      pos 1503
      pos 7716
  term 6vt
    doc 10
      freq 1
      pos 12718
  term 6x1xynpr7p
    doc 11
      freq 1
      pos 10160
  term 6x9occdroogjuglwok74qjqavjyt3o3o93f6e3b958zz2cdvq
    doc 10
      freq 1
      pos 12554
  term 6y7
    doc 11
      freq 1
      pos 10090
  term 7
    doc 0
      freq 21
      pos 168
      pos 217
      pos 1352
      pos 1399
      pos 1992
      pos 2707
      pos 5165
      pos 5899
      pos 6775
      pos 7540
      pos 8125
      pos 8708
      pos 9172
      pos 10535
      pos 11399
      pos 11666
      pos 11959
      pos 12495
      pos 13325
      pos 15733
      pos 15976
    doc 1
      freq 30
      pos 234
      pos 240
      pos 243
      pos 362
      pos 2224
      pos 2461
      pos 2471
      pos 2481
      pos 3647
      pos 3657
      pos 3667
      pos 4009
      pos 4019
      pos 4029
      pos 4085
      pos 4095
      pos 4105
      pos 5075
      pos 5085
      pos 5095
      pos 5244
      pos 5254
      pos 5264
      pos 5706
      pos 5716
      pos 5726
      pos 6041
      pos 6051
      pos 6061
      pos 7740
    doc 2
      freq 2
      pos 161
      pos 2452
    doc 3
      freq 11
      pos 198
      pos 203
      pos 275
      pos 1776
      pos 3642
      pos 3652
      pos 3662
      pos 4306
      pos 5685
      pos 5764
      pos 5773
    doc 4
      freq 24
      pos 259
      pos 597
      pos 607
      pos 617
      pos 2075
      pos 2103
      pos 2113
      pos 2123
      pos 2769
      pos 2779
      pos 2789
      pos 3014
      pos 3024
      pos 3034
      pos 3250
      pos 3260
      pos 3270
      pos 3557
      pos 3567
      pos 3577
      pos 3728
      pos 3738
      pos 3748
      pos 5171
    doc 5
      freq 16
      pos 283
      pos 331
      pos 1390
      pos 1583
      pos 1593
      pos 1603
      pos 1805
      pos 1815
      pos 1825
      pos 1956
      pos 2025
      pos 2044
      pos 2620
      pos 2630
      pos 2640
      pos 4063
    doc 6
      freq 4
      pos 2113
      pos 2119
      pos 2755
      pos 3086
    doc 7
      freq 3
      pos 144
      pos 1730
      pos 2176
    doc 8
      freq 5
      pos 167
      pos 170
      pos 174
      pos 178
      pos 1928
    doc 9
      freq 2
      pos 1354
      pos 2128
    doc 10
      freq 7
      pos 199
      pos 212
      pos 2513
      pos 4309
      pos 5523
      pos 12685
      pos 13200
    doc 11
      freq 4
      pos 1571
      pos 4286
      pos 5946
      pos 10141
    doc 12
      freq 5
      pos 252
      pos 262
      pos 369
      pos 2276
      pos 4918
    doc 13
      freq 13
      pos 165
      pos 171
      pos 179
      pos 335
      pos 607
      pos 1962
      pos 2169
      pos 4275
      pos 5541
      pos 5965
      pos 6342
      pos 6732
      pos 6810
    doc 14
      freq 5
      pos 178
      pos 183
      pos 268
      pos 2158
      pos 5335
    doc 15
      freq 5
      pos 257
      pos 262
      pos 290
      pos 2145
      pos 3830
    doc 16
      freq 5
      pos 1423
      pos 1439
      pos 1597
      pos 1854
      pos 2605
    doc 17
      freq 7
      pos 541
      pos 878
      pos 903
      pos 2111
      pos 2184
      pos 2224
      pos 2249
    doc 18
      freq 3
      pos 179
      pos 2056
      pos 2193
    skipList 
      level 0
        skipDoc 7
        skipDocFP 202374
        impacts 
          impact 
            freq 3
            norm 100
          impact 
            freq 4
            norm 101
          impact 
            freq 16
            norm 104
          impact 
            freq 24
            norm 108
          impact 
            freq 30
            norm 113
        impactsEnd 
        skipDoc 15
        skipDocFP 204219
        impacts 
          impact 
            freq 2
            norm 95
          impact 
            freq 5
            norm 97
          impact 
            freq 13
            norm 109
        impactsEnd 
  term 7.0
    doc 11
      freq 2
      pos 6677
      pos 6680
  term 7.1
    doc 0
      freq 1
      pos 15993
    doc 1
      freq 2
      pos 366
      pos 7743
    doc 4
      freq 2
      pos 262
      pos 5173
    doc 12
      freq 3
      pos 376
      pos 1430
      pos 4955
  term 7.2
    doc 0
      freq 1
      pos 16214
    doc 1
      freq 2
      pos 371
      pos 7793
    doc 4
      freq 2
      pos 266
      pos 5300
    doc 12
      freq 3
      pos 382
      pos 5258
      pos 6351
  term 7.2.1
    doc 0
      freq 1
      pos 16244
  term 7.2.10
    doc 0
      freq 1
      pos 16572
  term 7.2.11
    doc 0
      freq 1
      pos 16612
  term 7.2.12
    doc 0
      freq 1
      pos 16641
  term 7.2.13
    doc 0
      freq 1
      pos 16660
  term 7.2.2
    doc 0
      freq 3
      pos 1737
      pos 1842
      pos 16273
  term 7.2.3
    doc 0
      freq 1
      pos 16327
  term 7.2.4
    doc 0
      freq 1
      pos 16347
  term 7.2.5
    doc 0
      freq 1
      pos 16379
  term 7.2.6
    doc 0
      freq 1
      pos 16411
  term 7.2.7
    doc 0
      freq 2
      pos 1983
      pos 16489
  term 7.2.8
    doc 0
      freq 1
      pos 16516
  term 7.2.9
    doc 0
      freq 1
      pos 16544
  term 7.3
    doc 1
      freq 2
      pos 376
      pos 7896
    doc 12
      freq 3
      pos 389
      pos 5428
      pos 6138
  term 7.4
    doc 12
      freq 2
      pos 396
      pos 5949
  term 7.5
    doc 12
      freq 2
      pos 401
      pos 6157
  term 70
    doc 0
      freq 1
      pos 12175
    doc 10
      freq 5
      pos 6352
      pos 6637
      pos 6987
      pos 7124
      pos 7337
    doc 11
      freq 18
      pos 2375
      pos 2590
      pos 2690
      pos 3150
      pos 3628
      pos 3793
      pos 5822
      pos 6168
      pos 6358
      pos 6450
      pos 6611
      pos 6687
      pos 7659
      pos 7865
      pos 8140
      pos 8739
      pos 8829
      pos 8928
  term 7042
    doc 11
      freq 1
      pos 10606
  term 7043
    doc 7
      freq 1
      pos 2926
  term 707
    doc 1
      freq 1
      pos 9137
  term 7075
    doc 18
      freq 1
      pos 2163
  term 709
    doc 3
      freq 1
      pos 4807
  term 71
    doc 0
      freq 1
      pos 12311
  term 71g76xu8sbiy2l1puecbs9drb4ac5
    doc 11
      freq 1
      pos 9988
  term 72
    doc 0
      freq 1
      pos 12464
    doc 11
      freq 3
      pos 887
      pos 2204
      pos 2239
  term 7272939
    doc 11
      freq 20
      pos 1537
      pos 2255
      pos 3173
      pos 3406
      pos 4049
      pos 4314
      pos 4495
      pos 4709
      pos 5200
      pos 5357
      pos 5505
      pos 5665
      pos 5985
      pos 6209
      pos 6899
      pos 7233
      pos 8189
      pos 8518
      pos 9113
      pos 9290
  term 72nd
    doc 17
      freq 1
      pos 2372
  term 73
    doc 0
      freq 2
      pos 6492
      pos 12636
    doc 11
      freq 1
      pos 10293
  term 738
    doc 16
      freq 1
      pos 1942
  term 74
    doc 0
      freq 1
      pos 12784
  term 7465
    doc 15
      freq 1
      pos 4041
  term 746bz4eotj7yz0qunqhx
    doc 10
      freq 1
      pos 12571
  term 74j0pvvh
    doc 11
      freq 1
      pos 10082
  term 75
    doc 0
      freq 2
      pos 6773
      pos 12989
  term 7525
    doc 7
      freq 1
      pos 2914
  term 75f
    doc 10
      freq 1
      pos 12705
  term 75se
    doc 11
      freq 1
      pos 2203
  term 76
    doc 0
      freq 1
      pos 13180
  term 77
    doc 0
      freq 1
      pos 13339
  term 78
    doc 0
      freq 4
      pos 8992
      pos 13539
      pos 17245
      pos 17418
    doc 1
      freq 2
      pos 9626
      pos 9799
    doc 2
      freq 2
      pos 6423
      pos 6596
    doc 3
      freq 2
      pos 5975
      pos 6148
    doc 4
      freq 3
      pos 5295
      pos 6130
      pos 6303
    doc 5
      freq 2
      pos 4460
      pos 4633
    doc 6
      freq 2
      pos 3255
      pos 3433
    doc 7
      freq 2
      pos 2965
      pos 3138
    doc 8
      freq 2
      pos 2182
      pos 2355
    doc 9
      freq 2
      pos 1827
      pos 2000
    doc 10
      freq 2
      pos 13488
      pos 13661
    doc 11
      freq 2
      pos 10649
      pos 10822
    doc 12
      freq 2
      pos 9499
      pos 9672
    doc 13
      freq 2
      pos 7114
      pos 7287
    doc 14
      freq 2
      pos 5580
      pos 5753
    doc 15
      freq 2
      pos 4099
      pos 4272
    doc 16
      freq 2
      pos 2710
      pos 2883
    doc 17
      freq 2
      pos 2434
      pos 2607
    doc 18
      freq 2
      pos 2222
      pos 2395
    skipList 
      level 0
        skipDoc 7
        skipDocFP 209553
        impacts 
          impact 
            freq 2
            norm 100
          impact 
            freq 3
            norm 108
          impact 
            freq 4
            norm 120
        impactsEnd 
        skipDoc 15
        skipDocFP 210025
        impacts 
          impact 
            freq 2
            norm 95
        impactsEnd 
  term 78340
    doc 17
      freq 1
      pos 2390
  term 785799047
    doc 16
      freq 4
      pos 2402
      pos 2419
      pos 2438
      pos 2458
  term 78l
    doc 11
      freq 1
      pos 10454
  term 79
    doc 0
      freq 3
      pos 9070
      pos 13733
      pos 17421
    doc 1
      freq 1
      pos 9802
    doc 2
      freq 1
      pos 6599
    doc 3
      freq 1
      pos 6151
    doc 4
      freq 1
      pos 6306
    doc 5
      freq 1
      pos 4636
    doc 6
      freq 1
      pos 3436
    doc 7
      freq 1
      pos 3141
    doc 8
      freq 1
      pos 2358
    doc 9
      freq 1
      pos 2003
    doc 10
      freq 1
      pos 13664
    doc 11
      freq 1
      pos 10825
    doc 12
      freq 1
      pos 9675
    doc 13
      freq 1
      pos 7290
    doc 14
      freq 1
      pos 5756
    doc 15
      freq 1
      pos 4275
    doc 16
      freq 1
      pos 2886
    doc 17
      freq 1
      pos 2610
    doc 18
      freq 1
      pos 2398
    skipList 
      level 0
        skipDoc 7
        skipDocFP 211255
        impacts 
          impact 
            freq 1
            norm 100
          impact 
            freq 3
            norm 120
        impactsEnd 
        skipDoc 15
        skipDocFP 211591
        impacts 
          impact 
            freq 1
            norm 95
        impactsEnd 
  term 792
    doc 4
      freq 3
      pos 300
      pos 5213
      pos 5223
  term 79h8yxlp
    doc 11
      freq 1
      pos 9940
  term 79ucoglcnqgzaeh
    doc 10
      freq 1
      pos 12620
  term 7a9cbec02ceef655
    doc 11
      freq 4
      pos 3838
      pos 3856
      pos 3866
      pos 3914
  term 7alm
    doc 10
      freq 1
      pos 6280
  term 7bit
    doc 16
      freq 2
      pos 2041
      pos 2219
  term 7bl
    doc 11
      freq 1
      pos 10385
  term 7e73
    doc 11
      freq 1
      pos 10095
  term 7f
    doc 11
      freq 1
      pos 1953
  term 7f2g9bjtfzi3gj9rdixzlpn2tznvbflhlcjj9pf
    doc 11
      freq 1
      pos 10354
  term 7gv
    doc 11
      freq 1
      pos 10444
  term 7jn59
    doc 10
      freq 1
      pos 12717
  term 7l5
    doc 10
      freq 1
      pos 12813
  term 7laxvtmugkksewhwthtctt4umb4crjnlj
    doc 10
      freq 1
      pos 12659
  term 7lr
    doc 14
      freq 1
      pos 5534
  term 7nmqulohfihxviqt2f06ua0loo2nvofk9g7mtkvbvniyallyudej7xwldicf3zhl
    doc 10
      freq 1
      pos 6835
  term 7ob
    doc 11
      freq 1
      pos 10158
  term 7p
    doc 11
      freq 1
      pos 10464
  term 7pzb
    doc 11
      freq 1
      pos 10267
  term 7tmhdq3wqlmk9nlkt3a0z2rhgglcq8jmtub
    doc 10
      freq 1
      pos 12511
  term 8
    doc 0
      freq 25
      pos 172
      pos 1369
      pos 1503
      pos 1580
      pos 1611
      pos 2069
      pos 2766
      pos 5195
      pos 5932
      pos 6832
      pos 7144
      pos 7567
      pos 8174
      pos 8753
      pos 9230
      pos 10611
      pos 11450
      pos 11668
      pos 11830
      pos 11978
      pos 12525
      pos 13404
      pos 15762
      pos 16734
      pos 16882
    doc 1
      freq 30
      pos 247
      pos 253
      pos 382
      pos 2420
      pos 2462
      pos 2472
      pos 2482
      pos 3648
      pos 3658
      pos 3668
      pos 4010
      pos 4020
      pos 4030
      pos 4086
      pos 4096
      pos 4106
      pos 5076
      pos 5086
      pos 5096
      pos 5245
      pos 5255
      pos 5265
      pos 5707
      pos 5717
      pos 5727
      pos 6042
      pos 6052
      pos 6062
      pos 6278
      pos 7927
    doc 2
      freq 1
      pos 2696
    doc 3
      freq 11
      pos 208
      pos 217
      pos 279
      pos 2115
      pos 3643
      pos 3653
      pos 3663
      pos 4227
      pos 4511
      pos 5656
      pos 5686
    doc 4
      freq 26
      pos 185
      pos 190
      pos 270
      pos 598
      pos 608
      pos 618
      pos 2104
      pos 2114
      pos 2124
      pos 2312
      pos 2770
      pos 2780
      pos 2790
      pos 3015
      pos 3025
      pos 3035
      pos 3251
      pos 3261
      pos 3271
      pos 3558
      pos 3568
      pos 3578
      pos 3729
      pos 3739
      pos 3749
      pos 5449
    doc 5
      freq 22
      pos 287
      pos 334
      pos 1404
      pos 1584
      pos 1594
      pos 1604
      pos 1622
      pos 1643
      pos 1685
      pos 1806
      pos 1816
      pos 1826
      pos 1834
      pos 1843
      pos 1962
      pos 2355
      pos 2621
      pos 2631
      pos 2641
      pos 2652
      pos 2661
      pos 4117
    doc 6
      freq 1
      pos 3032
    doc 7
      freq 3
      pos 148
      pos 1764
      pos 2534
    doc 8
      freq 6
      pos 828
      pos 1085
      pos 1156
      pos 1337
      pos 1501
      pos 2151
    doc 10
      freq 5
      pos 218
      pos 2968
      pos 4674
      pos 5534
      pos 13212
    doc 11
      freq 24
      pos 148
      pos 1014
      pos 1739
      pos 1895
      pos 3343
      pos 3351
      pos 3378
      pos 3385
      pos 3531
      pos 3964
      pos 4291
      pos 4471
      pos 5178
      pos 5625
      pos 6784
      pos 6876
      pos 7130
      pos 7760
      pos 8052
      pos 8925
      pos 9092
      pos 10292
      pos 10372
      pos 10416
    doc 12
      freq 5
      pos 274
      pos 284
      pos 408
      pos 2647
      pos 6491
    doc 13
      freq 9
      pos 187
      pos 339
      pos 1178
      pos 1829
      pos 2561
      pos 5593
      pos 5980
      pos 6754
      pos 6828
    doc 14
      freq 8
      pos 188
      pos 192
      pos 201
      pos 226
      pos 271
      pos 2549
      pos 4469
      pos 5357
    doc 15
      freq 4
      pos 267
      pos 293
      pos 2591
      pos 3895
    doc 16
      freq 5
      pos 1446
      pos 1472
      pos 1638
      pos 2112
      pos 2621
    doc 17
      freq 1
      pos 2149
    doc 18
      freq 1
      pos 2524
    skipList 
      level 0
        skipDoc 7
        skipDocFP 213684
        impacts 
          impact 
            freq 3
            norm 100
          impact 
            freq 22
            norm 104
          impact 
            freq 26
            norm 108
          impact 
            freq 30
            norm 113
        impactsEnd 
        skipDoc 16
        skipDocFP 215652
        impacts 
          impact 
            freq 6
            norm 97
          impact 
            freq 8
            norm 107
          impact 
            freq 9
            norm 109
          impact 
            freq 24
            norm 114
        impactsEnd 
  term 8.1
    doc 1
      freq 2
      pos 386
      pos 7988
    doc 4
      freq 1
      pos 1296
    doc 5
      freq 2
      pos 337
      pos 4119
    doc 12
      freq 2
      pos 413
      pos 6518
    doc 14
      freq 2
      pos 274
      pos 5359
  term 8.2
    doc 1
      freq 2
      pos 391
      pos 8402
    doc 5
      freq 2
      pos 341
      pos 4238
    doc 12
      freq 2
      pos 420
      pos 6567
    doc 14
      freq 2
      pos 278
      pos 5465
  term 80
    doc 0
      freq 2
      pos 9114
      pos 13923
    doc 1
      freq 1
      pos 6267
    doc 5
      freq 2
      pos 1375
      pos 1941
    doc 11
      freq 1
      pos 4454
  term 800
    doc 1
      freq 1
      pos 9577
    doc 6
      freq 1
      pos 3207
  term 8000
    doc 10
      freq 3
      pos 6404
      pos 6541
      pos 6704
  term 80021
    doc 1
      freq 1
      pos 9534
    doc 3
      freq 1
      pos 5899
  term 80112
    doc 1
      freq 1
      pos 9518
    doc 3
      freq 1
      pos 5883
    doc 8
      freq 1
      pos 2142
  term 802
    doc 2
      freq 110
      pos 19
      pos 64
      pos 126
      pos 198
      pos 212
      pos 324
      pos 345
      pos 371
      pos 428
      pos 439
      pos 446
      pos 451
      pos 479
      pos 487
      pos 549
      pos 559
      pos 614
      pos 627
      pos 661
      pos 672
      pos 686
      pos 691
      pos 697
      pos 716
      pos 728
      pos 733
      pos 748
      pos 754
      pos 757
      pos 761
      pos 777
      pos 792
      pos 824
      pos 842
      pos 857
      pos 862
      pos 905
      pos 953
      pos 986
      pos 1003
      pos 1017
      pos 1036
      pos 1067
      pos 1077
      pos 1092
      pos 1103
      pos 1161
      pos 1192
      pos 1227
      pos 1242
      pos 1264
      pos 1291
      pos 1296
      pos 1308
      pos 1372
      pos 1408
      pos 1471
      pos 1480
      pos 1552
      pos 1613
      pos 1622
      pos 1628
      pos 1714
      pos 1731
      pos 1792
      pos 1811
      pos 1821
      pos 1846
      pos 1910
      pos 1918
      pos 1945
      pos 1985
      pos 2025
      pos 2060
      pos 2093
      pos 2188
      pos 2219
      pos 2287
      pos 2293
      pos 2431
      pos 2456
      pos 2700
      pos 2878
      pos 2949
      pos 3205
      pos 3446
      pos 3489
      pos 3512
      pos 3729
      pos 3753
      pos 3872
      pos 4141
      pos 4256
      pos 4494
      pos 4507
      pos 4664
      pos 5002
      pos 5025
      pos 5358
      pos 5383
      pos 5393
      pos 5407
      pos 5421
      pos 5447
      pos 5668
      pos 5826
      pos 6219
      pos 6299
      pos 6333
      pos 6396
  term 802.1
    doc 2
      freq 19
      pos 1327
      pos 1339
      pos 1353
      pos 1364
      pos 2839
      pos 3625
      pos 3647
      pos 4218
      pos 4335
      pos 4358
      pos 4435
      pos 4843
      pos 4907
      pos 4984
      pos 5131
      pos 5203
      pos 5536
      pos 5623
      pos 5662
  term 802.11
    doc 2
      freq 27
      pos 1379
      pos 1761
      pos 1782
      pos 2004
      pos 2113
      pos 2353
      pos 2420
      pos 2622
      pos 2656
      pos 4931
      pos 4936
      pos 4956
      pos 5434
      pos 5631
      pos 5633
      pos 5642
      pos 5645
      pos 5659
      pos 5690
      pos 5696
      pos 5725
      pos 5749
      pos 5817
      pos 5857
      pos 5890
      pos 6016
      pos 6027
  term 802.11f
    doc 2
      freq 13
      pos 1641
      pos 2391
      pos 2423
      pos 4939
      pos 6040
      pos 6042
      pos 6133
      pos 6231
      pos 6252
      pos 6259
      pos 6284
      pos 6290
      pos 6320
  term 802.11r
    doc 2
      freq 1
      pos 5961
  term 802.16
    doc 2
      freq 10
      pos 1382
      pos 1437
      pos 1454
      pos 1459
      pos 1462
      pos 2706
      pos 2749
      pos 2755
      pos 2772
      pos 2778
  term 802.1d
    doc 2
      freq 6
      pos 2521
      pos 2552
      pos 3526
      pos 3533
      pos 3604
      pos 4685
  term 802.1p
    doc 2
      freq 2
      pos 4106
      pos 4113
    doc 3
      freq 1
      pos 5802
  term 802.1q
    doc 2
      freq 5
      pos 2556
      pos 4115
      pos 4117
      pos 4687
      pos 4709
    doc 3
      freq 15
      pos 314
      pos 1143
      pos 1144
      pos 1193
      pos 1391
      pos 2043
      pos 3795
      pos 3897
      pos 4446
      pos 4450
      pos 5600
      pos 5623
      pos 5628
      pos 5654
      pos 5778
  term 802.1t
    doc 2
      freq 2
      pos 4671
      pos 4677
  term 802.1u
    doc 2
      freq 2
      pos 4672
      pos 4679
  term 802.1v
    doc 2
      freq 2
      pos 4673
      pos 4698
  term 802.1w
    doc 2
      freq 2
      pos 4675
      pos 4715
  term 802.1x
    doc 2
      freq 45
      pos 280
      pos 1376
      pos 2462
      pos 2472
      pos 2480
      pos 2500
      pos 2859
      pos 3171
      pos 4369
      pos 4379
      pos 4474
      pos 4583
      pos 4586
      pos 4618
      pos 4623
      pos 4776
      pos 4855
      pos 4892
      pos 4925
      pos 4928
      pos 4988
      pos 4990
      pos 4993
      pos 5015
      pos 5035
      pos 5082
      pos 5097
      pos 5108
      pos 5115
      pos 5250
      pos 5281
      pos 5283
      pos 5303
      pos 5318
      pos 5329
      pos 5353
      pos 5430
      pos 5455
      pos 5544
      pos 5599
      pos 5648
      pos 5653
      pos 5700
      pos 5708
      pos 5733
  term 802.3
    doc 2
      freq 15
      pos 2577
      pos 2618
      pos 2933
      pos 3236
      pos 3425
      pos 3677
      pos 3708
      pos 3711
      pos 3786
      pos 3860
      pos 3885
      pos 4013
      pos 4028
      pos 4065
      pos 4090
    doc 3
      freq 8
      pos 109
      pos 138
      pos 349
      pos 350
      pos 2927
      pos 2928
      pos 4401
      pos 4469
  term 802.3ad
    doc 2
      freq 6
      pos 4367
      pos 4376
      pos 4432
      pos 4471
      pos 4536
      pos 4564
  term 802.3x
    doc 3
      freq 5
      pos 249
      pos 300
      pos 3143
      pos 3179
      pos 5279
  term 802.5
    doc 7
      freq 2
      pos 1070
      pos 2644
  term 80211
    doc 2
      freq 1
      pos 2388
  term 80211liaison1
    doc 2
      freq 2
      pos 2351
      pos 5758
  term 80211liaison2
    doc 2
      freq 2
      pos 2368
      pos 5810
  term 802liaison
    doc 2
      freq 2
      pos 844
      pos 2429
  term 81
    doc 0
      freq 1
      pos 14134
  term 813gvyjcbuazngqmxc9wnzsdn
    doc 11
      freq 1
      pos 3804
  term 81739
    doc 5
      freq 2
      pos 4407
      pos 4421
  term 82
    doc 0
      freq 2
      pos 9228
      pos 14321
    doc 8
      freq 1
      pos 1031
  term 822
    doc 7
      freq 2
      pos 920
      pos 2384
  term 82zf
    doc 11
      freq 1
      pos 10403
  term 83
    doc 0
      freq 2
      pos 9140
      pos 14498
  term 8301
    doc 7
      freq 1
      pos 2908
  term 838293
    doc 11
      freq 1
      pos 8834
  term 8392034
    doc 11
      freq 1
      pos 7862
  term 839923423
    doc 11
      freq 1
      pos 2372
  term 84
    doc 0
      freq 2
      pos 9429
      pos 14664
    doc 7
      freq 2
      pos 936
      pos 2400
    doc 12
      freq 1
      pos 7539
  term 8473
    doc 0
      freq 1
      pos 16912
  term 85
    doc 0
      freq 2
      pos 9284
      pos 14802
    doc 4
      freq 1
      pos 4938
  term 858
    doc 16
      freq 1
      pos 2666
  term 8588
    doc 13
      freq 1
      pos 7002
  term 86
    doc 0
      freq 2
      pos 9314
      pos 14922
  term 87
    doc 0
      freq 1
      pos 15049
    doc 10
      freq 1
      pos 12460
    doc 11
      freq 1
      pos 2215
  term 8720
    doc 10
      freq 1
      pos 13422
  term 87321hj23128
    doc 11
      freq 1
      pos 8049
  term 8735
    doc 14
      freq 1
      pos 5539
  term 878
    doc 7
      freq 1
      pos 2913
  term 88
    doc 0
      freq 1
      pos 15176
    doc 7
      freq 2
      pos 932
      pos 2396
  term 8802
    doc 2
      freq 1
      pos 2580
    doc 3
      freq 1
      pos 4406
  term 8814
    doc 11
      freq 1
      pos 5633
  term 8824
    doc 17
      freq 1
      pos 2097
  term 89
    doc 0
      freq 1
      pos 15306
  term 8e9
    doc 3
      freq 1
      pos 4881
  term 8el9r
    doc 11
      freq 1
      pos 10499
  term 8fciljv0rf
    doc 11
      freq 1
      pos 10299
  term 8fzhgs4aq5stuedwqntyhk08lextthqrivwhwiu3ppxnm7j7t
    doc 11
      freq 1
      pos 10092
  term 8jb
    doc 10
      freq 1
      pos 12601
  term 8k7c6h
    doc 11
      freq 1
      pos 10125
  term 8kce8rasxwnlixalzrl0p4ogyshjkv1lyr9czdjwp7cwqv
    doc 11
      freq 1
      pos 10457
  term 8lanl5p8yd
    doc 11
      freq 1
      pos 10168
  term 8ozrv
    doc 11
      freq 1
      pos 10268
  term 8pxgll7gy
    doc 10
      freq 1
      pos 12723
  term 8pxmkx
    doc 10
      freq 1
      pos 6230
  term 8q9wf
    doc 10
      freq 1
      pos 12727
  term 8qa
    doc 10
      freq 1
      pos 12726
  term 8sfqaudtdyfcrtrgk0ofltglqewu2okgilyds
    doc 11
      freq 1
      pos 9952
  term 8snuxx2
    doc 11
      freq 1
      pos 10254
  term 8ulhkot1ubobsqtnrezwi5g436tksgkxzyvkxr9bybtdcft
    doc 10
      freq 1
      pos 12781
  term 8wf
    doc 10
      freq 1
      pos 12731
  term 8wt8mv
    doc 10
      freq 1
      pos 12710
  term 9
    doc 0
      freq 19
      pos 176
      pos 1385
      pos 1777
      pos 2800
      pos 4800
      pos 5219
      pos 6015
      pos 6926
      pos 7603
      pos 8208
      pos 8793
      pos 9286
      pos 10709
      pos 11494
      pos 11670
      pos 12569
      pos 13490
      pos 15792
      pos 17128
    doc 1
      freq 27
      pos 396
      pos 2463
      pos 2473
      pos 2483
      pos 2694
      pos 3649
      pos 3659
      pos 3669
      pos 4011
      pos 4021
      pos 4031
      pos 4087
      pos 4097
      pos 4107
      pos 5077
      pos 5087
      pos 5097
      pos 5246
      pos 5256
      pos 5266
      pos 5708
      pos 5718
      pos 5728
      pos 6043
      pos 6053
      pos 6063
      pos 8870
    doc 2
      freq 1
      pos 2945
    doc 3
      freq 8
      pos 221
      pos 228
      pos 283
      pos 2426
      pos 3644
      pos 3654
      pos 3664
      pos 4748
    doc 4
      freq 22
      pos 599
      pos 609
      pos 619
      pos 2105
      pos 2115
      pos 2125
      pos 2716
      pos 2771
      pos 2781
      pos 2791
      pos 3016
      pos 3026
      pos 3036
      pos 3252
      pos 3262
      pos 3272
      pos 3559
      pos 3569
      pos 3579
      pos 3730
      pos 3740
      pos 3750
    doc 5
      freq 14
      pos 1433
      pos 1585
      pos 1595
      pos 1605
      pos 1807
      pos 1817
      pos 1827
      pos 1971
      pos 1986
      pos 2037
      pos 2552
      pos 2622
      pos 2632
      pos 2642
    doc 6
      freq 1
      pos 3222
    doc 7
      freq 4
      pos 151
      pos 1800
      pos 1813
      pos 2889
    doc 8
      freq 1
      pos 2484
    doc 10
      freq 11
      pos 224
      pos 2261
      pos 3297
      pos 3366
      pos 3372
      pos 4117
      pos 4215
      pos 4762
      pos 10991
      pos 11499
      pos 13226
    doc 11
      freq 3
      pos 156
      pos 2109
      pos 10330
    doc 12
      freq 8
      pos 295
      pos 302
      pos 429
      pos 3019
      pos 6745
      pos 8272
      pos 8305
      pos 8668
    doc 13
      freq 8
      pos 195
      pos 201
      pos 208
      pos 343
      pos 1554
      pos 2932
      pos 6854
      pos 6952
    doc 14
      freq 3
      pos 229
      pos 2608
      pos 2903
    doc 15
      freq 3
      pos 276
      pos 2566
      pos 3003
    doc 16
      freq 2
      pos 2249
      pos 2519
    doc 17
      freq 1
      pos 2318
    skipList 
      level 0
        skipDoc 7
        skipDocFP 227008
        impacts 
          impact 
            freq 4
            norm 100
          impact 
            freq 14
            norm 104
          impact 
            freq 22
            norm 108
          impact 
            freq 27
            norm 113
        impactsEnd 
        skipDoc 16
        skipDocFP 228634
        impacts 
          impact 
            freq 1
            norm 97
          impact 
            freq 2
            norm 99
          impact 
            freq 3
            norm 104
          impact 
            freq 8
            norm 109
          impact 
            freq 11
            norm 116
        impactsEnd 
  term 9.1
    doc 12
      freq 1
      pos 7631
  term 9.5
    doc 0
      freq 1
      pos 2012
  term 9.8
    doc 0
      freq 1
      pos 1572
  term 90
    doc 0
      freq 1
      pos 15417
    doc 1
      freq 1
      pos 9286
    doc 3
      freq 1
      pos 4755
  term 900
    doc 0
      freq 1
      pos 2603
  term 902
    doc 10
      freq 1
      pos 13449
  term 902jndnke3
    doc 11
      freq 2
      pos 4155
      pos 6993
  term 91
    doc 0
      freq 1
      pos 15488
    doc 12
      freq 1
      pos 7340
  term 9155
    doc 1
      freq 1
      pos 9510
    doc 3
      freq 1
      pos 5875
    doc 8
      freq 1
      pos 2134
  term 92
    doc 0
      freq 1
      pos 15559
  term 92121
    doc 16
      freq 1
      pos 2661
  term 925
    doc 10
      freq 1
      pos 13420
  term 9292394834772304023312
    doc 11
      freq 1
      pos 5046
  term 93
    doc 0
      freq 1
      pos 15637
    doc 10
      freq 1
      pos 6867
    doc 11
      freq 1
      pos 10264
  term 93334
    doc 11
      freq 1
      pos 5166
  term 9338
    doc 11
      freq 1
      pos 8057
  term 938
    doc 11
      freq 1
      pos 2212
  term 939
    doc 11
      freq 1
      pos 10605
  term 93942939o2
    doc 11
      freq 1
      pos 4462
  term 93d10c42102e7b7289d29cc0c9ae2efb
    doc 11
      freq 1
      pos 3909
  term 93yv
    doc 10
      freq 1
      pos 12688
  term 94
    doc 0
      freq 1
      pos 15721
  term 94043
    doc 3
      freq 2
      pos 4969
      pos 4983
    doc 9
      freq 1
      pos 1776
  term 94085
    doc 4
      freq 1
      pos 6084
  term 94089
    doc 1
      freq 2
      pos 9362
      pos 9376
    doc 3
      freq 1
      pos 4866
  term 94520
    doc 10
      freq 1
      pos 13416
  term 949302838503028349304023988
    doc 11
      freq 1
      pos 5053
  term 95
    doc 0
      freq 1
      pos 15798
  term 95014
    doc 3
      freq 1
      pos 4955
  term 95054
    doc 3
      freq 1
      pos 4896
  term 95134
    doc 1
      freq 4
      pos 9213
      pos 9246
      pos 9293
      pos 9307
    doc 3
      freq 1
      pos 4762
    doc 4
      freq 1
      pos 6070
    doc 10
      freq 1
      pos 13444
  term 952
    doc 11
      freq 1
      pos 10577
  term 96
    doc 0
      freq 4
      pos 164
      pos 167
      pos 171
      pos 16130
  term 960
    doc 1
      freq 1
      pos 9357
  term 97
    doc 0
      freq 1
      pos 16319
  term 973
    doc 11
      freq 1
      pos 10576
  term 97f
    doc 10
      freq 1
      pos 12711
  term 97rpvb3k
    doc 10
      freq 1
      pos 12593
  term 98
    doc 0
      freq 2
      pos 10227
      pos 16471
  term 98052
    doc 2
      freq 1
      pos 6384
  term 980mfctdixqnc
    doc 11
      freq 1
      pos 10458
  term 982
    doc 11
      freq 1
      pos 2853
  term 9834
    doc 17
      freq 1
      pos 2009
  term 98asjd8
    doc 11
      freq 1
      pos 1468
  term 99
    doc 0
      freq 2
      pos 10497
      pos 16604
  term 9921883
    doc 11
      freq 1
      pos 5463
  term 998332
    doc 11
      freq 1
      pos 6355
  term 999
    doc 11
      freq 1
      pos 4703
  term 9999
    doc 11
      freq 1
      pos 4489
  term 99qn4jidwzjydwht3vy21aq3cf1xf
    doc 11
      freq 1
      pos 10137
  term 9bwv83hvxpsp4n
    doc 11
      freq 1
      pos 10306
  term 9dnf
    doc 10
      freq 1
      pos 12729
  term 9f
    doc 11
      freq 1
      pos 10259
  term 9hy43r
    doc 10
      freq 1
      pos 12678
  term 9kldez
    doc 10
      freq 1
      pos 6848
  term 9m0haigdfk5qzehzenk2tn0ughc00dcrptu0vzn8yqldrt6d45r
    doc 11
      freq 1
      pos 9989
  term 9o4v9dn3k
    doc 10
      freq 1
      pos 12752
  term 9rckp9jjf
    doc 11
      freq 1
      pos 10359
  term 9rjplyowrtdag6jfhwp0
    doc 11
      freq 1
      pos 9877
  term 9sfie
    doc 11
      freq 1
      pos 10493
  term 9tfieqxty9azafd
    doc 10
      freq 1
      pos 6264
  term 9th
    doc 1
      freq 1
      pos 9345
    doc 3
      freq 1
      pos 4848
  term 9us
    doc 11
      freq 1
      pos 10371
  term 9vlu
    doc 10
      freq 1
      pos 12681
  term 9w0
    doc 10
      freq 1
      pos 12709
  term 9xs0yxborsr4jtk
    doc 10
      freq 1
      pos 12772
  term 9xubxtufgqyvjqvyhers6rxx
    doc 10
      freq 1
      pos 6845
  term _token
    doc 11
      freq 1
      pos 1977
  term a.b
    doc 13
      freq 1
      pos 6908
  term a003
    doc 16
      freq 8
      pos 1773
      pos 1845
      pos 1934
      pos 2089
      pos 2154
      pos 2241
      pos 2303
      pos 2453
  term a004
    doc 16
      freq 2
      pos 2097
      pos 2104
  term a1ueawwsymlsb3hplmv4yw1wbguuy29tmb4xdta1mtaynda2ndaynloxdta2mtay
    doc 10
      freq 1
      pos 6882
  term a2cj
    doc 11
      freq 1
      pos 10463
  term a4oernzze4z
    doc 10
      freq 1
      pos 12509
  term a4qqzksse0pyvrf629ubir6awigcgnvenp0iiz5wjr4ezjniqr
    doc 10
      freq 1
      pos 12774
  term a5uo4xltmi9q3iiwdjbolonbuahd5ok7fnqu637t
    doc 10
      freq 1
      pos 12499
  term a6
    doc 12
      freq 2
      pos 809
      pos 838
  term a6c85cf
    doc 10
      freq 3
      pos 6993
      pos 7130
      pos 7343
  term a84b4c76e66710
    doc 10
      freq 7
      pos 6346
      pos 6484
      pos 6631
      pos 7002
      pos 7148
      pos 7234
      pos 7361
  term a95h
    doc 10
      freq 1
      pos 12687
  term aa
    doc 17
      freq 11
      pos 355
      pos 371
      pos 430
      pos 559
      pos 1027
      pos 1161
      pos 1383
      pos 1451
      pos 1505
      pos 1542
      pos 1898
  term aa's
    doc 17
      freq 1
      pos 1496
  term aaa
    doc 2
      freq 23
      pos 84
      pos 143
      pos 177
      pos 231
      pos 1477
      pos 1484
      pos 1516
      pos 1522
      pos 1662
      pos 1686
      pos 1699
      pos 1720
      pos 1749
      pos 2132
      pos 2145
      pos 2329
      pos 4836
      pos 4913
      pos 4947
      pos 5717
      pos 5975
      pos 6032
      pos 6237
  term aaaa
    doc 12
      freq 36
      pos 181
      pos 763
      pos 922
      pos 1041
      pos 1147
      pos 1206
      pos 1346
      pos 1724
      pos 1734
      pos 1767
      pos 2525
      pos 2580
      pos 2844
      pos 2861
      pos 2928
      pos 2943
      pos 2950
      pos 2987
      pos 3082
      pos 3098
      pos 3309
      pos 3449
      pos 3460
      pos 3489
      pos 3509
      pos 3541
      pos 3599
      pos 3685
      pos 6538
      pos 8265
      pos 8279
      pos 8375
      pos 8403
      pos 8423
      pos 8734
      pos 8917
  term aal1
    doc 8
      freq 1
      pos 772
  term aal2
    doc 8
      freq 1
      pos 783
  term aal5
    doc 1
      freq 2
      pos 1568
      pos 1606
    doc 8
      freq 2
      pos 639
      pos 716
  term aas
    doc 17
      freq 5
      pos 995
      pos 1306
      pos 1407
      pos 1464
      pos 1675
  term aawar
    doc 1
      freq 4
      pos 20
      pos 9053
      pos 9103
      pos 9524
    doc 3
      freq 3
      pos 20
      pos 4359
      pos 5889
    doc 8
      freq 3
      pos 1791
      pos 1942
      pos 1990
  term ab
    doc 18
      freq 2
      pos 20
      pos 2177
  term abbey
    doc 1
      freq 1
      pos 9542
    doc 3
      freq 1
      pos 5907
  term abc
    doc 11
      freq 1
      pos 1137
  term abcabcabc
    doc 11
      freq 1
      pos 1129
  term aberrant
    doc 11
      freq 1
      pos 4864
  term abides
    doc 17
      freq 1
      pos 202
  term ability
    doc 3
      freq 3
      pos 3288
      pos 3542
      pos 3864
  term able
    doc 0
      freq 1
      pos 6118
    doc 1
      freq 7
      pos 1352
      pos 1419
      pos 1436
      pos 1447
      pos 1589
      pos 1621
      pos 1647
    doc 2
      freq 1
      pos 2007
    doc 3
      freq 1
      pos 3557
    doc 5
      freq 3
      pos 3411
      pos 3431
      pos 3566
    doc 9
      freq 1
      pos 461
    doc 10
      freq 5
      pos 593
      pos 4523
      pos 7668
      pos 10867
      pos 12903
    doc 12
      freq 6
      pos 1466
      pos 1978
      pos 3680
      pos 3712
      pos 4160
      pos 4663
    doc 13
      freq 4
      pos 2047
      pos 2736
      pos 4354
      pos 5421
    doc 15
      freq 3
      pos 2301
      pos 2701
      pos 3141
    doc 17
      freq 2
      pos 235
      pos 1509
    skipList 
      level 0
        skipDoc 12
        skipDocFP 237762
        impacts 
          impact 
            freq 1
            norm 95
          impact 
            freq 3
            norm 104
          impact 
            freq 7
            norm 113
        impactsEnd 
  term abnf
    doc 10
      freq 5
      pos 4797
      pos 4992
      pos 5222
      pos 5318
      pos 13195
    doc 16
      freq 6
      pos 1422
      pos 1438
      pos 1444
      pos 1470
      pos 2616
      pos 2631
  term aboba
    doc 2
      freq 19
      pos 4
      pos 366
      pos 2283
      pos 2328
      pos 2338
      pos 2439
      pos 2758
      pos 2781
      pos 2795
      pos 3049
      pos 3104
      pos 3119
      pos 3136
      pos 3161
      pos 3264
      pos 3290
      pos 5198
      pos 6349
      pos 6377
  term about
    doc 0
      freq 15
      pos 735
      pos 841
      pos 865
      pos 4491
      pos 4573
      pos 4643
      pos 4663
      pos 6267
      pos 6287
      pos 8281
      pos 8310
      pos 9950
      pos 10867
      pos 11697
      pos 16593
    doc 1
      freq 1
      pos 818
    doc 4
      freq 1
      pos 6014
    doc 5
      freq 1
      pos 3613
    doc 7
      freq 1
      pos 1709
    doc 9
      freq 1
      pos 850
    doc 10
      freq 5
      pos 4403
      pos 6043
      pos 6109
      pos 8082
      pos 9757
    doc 11
      freq 2
      pos 7956
      pos 7982
    doc 12
      freq 20
      pos 133
      pos 187
      pos 353
      pos 371
      pos 535
      pos 555
      pos 688
      pos 789
      pos 942
      pos 1232
      pos 2001
      pos 4032
      pos 4205
      pos 4696
      pos 4920
      pos 4972
      pos 6500
      pos 6731
      pos 6753
      pos 9008
    doc 13
      freq 5
      pos 1556
      pos 5661
      pos 5705
      pos 5719
      pos 6035
    doc 14
      freq 1
      pos 2461
    doc 16
      freq 1
      pos 2012
    doc 18
      freq 3
      pos 434
      pos 549
      pos 723
    skipList 
      level 0
        skipDoc 11
        skipDocFP 239368
        impacts 
          impact 
            freq 1
            norm 95
          impact 
            freq 2
            norm 114
          impact 
            freq 5
            norm 116
          impact 
            freq 15
            norm 120
        impactsEnd 
  term above
    doc 1
      freq 7
      pos 1789
      pos 5442
      pos 5869
      pos 7088
      pos 7097
      pos 8131
      pos 8816
    doc 3
      freq 5
      pos 929
      pos 3676
      pos 3936
      pos 4022
      pos 5446
    doc 4
      freq 3
      pos 2042
      pos 2066
      pos 4986
    doc 5
      freq 4
      pos 853
      pos 2051
      pos 3786
      pos 4002
    doc 6
      freq 2
      pos 1853
      pos 1926
    doc 7
      freq 4
      pos 1215
      pos 1563
      pos 1595
      pos 1629
    doc 10
      freq 5
      pos 3622
      pos 5848
      pos 6552
      pos 6747
      pos 7255
    doc 11
      freq 2
      pos 643
      pos 3738
    doc 12
      freq 4
      pos 2694
      pos 6112
      pos 8221
      pos 9063
    doc 13
      freq 1
      pos 6399
    doc 14
      freq 2
      pos 1184
      pos 1336
    doc 15
      freq 1
      pos 3597
    doc 18
      freq 2
      pos 1262
      pos 1902
    skipList 
      level 0
        skipDoc 11
        skipDocFP 240871
        impacts 
          impact 
            freq 4
            norm 100
          impact 
            freq 5
            norm 107
          impact 
            freq 7
            norm 113
        impactsEnd 
  term absenc
    doc 2
      freq 1
      pos 5143
    doc 6
      freq 1
      pos 2430
    doc 10
      freq 5
      pos 503
      pos 9845
      pos 9950
      pos 11225
      pos 11373
  term absent
    doc 1
      freq 1
      pos 3034
    doc 11
      freq 1
      pos 4830
  term absolut
    doc 14
      freq 17
      pos 132
      pos 236
      pos 245
      pos 434
      pos 594
      pos 602
      pos 684
      pos 1175
      pos 1181
      pos 2695
      pos 2708
      pos 2735
      pos 2831
      pos 2882
      pos 2958
      pos 4150
      pos 5324
    doc 16
      freq 1
      pos 1006
  term absolutely
    doc 12
      freq 1
      pos 8864
  term absoluteur
    doc 10
      freq 2
      pos 4829
      pos 5567
  term abstract
    doc 0
      freq 1
      pos 88
    doc 1
      freq 1
      pos 105
    doc 2
      freq 1
      pos 58
    doc 3
      freq 1
      pos 99
    doc 4
      freq 2
      pos 101
      pos 5554
    doc 5
      freq 1
      pos 85
    doc 6
      freq 1
      pos 175
    doc 7
      freq 1
      pos 72
    doc 8
      freq 1
      pos 66
    doc 9
      freq 1
      pos 87
    doc 10
      freq 1
      pos 90
    doc 11
      freq 1
      pos 74
    doc 12
      freq 1
      pos 64
    doc 13
      freq 1
      pos 73
    doc 14
      freq 1
      pos 68
    doc 15
      freq 1
      pos 72
    doc 16
      freq 1
      pos 86
    doc 17
      freq 3
      pos 83
      pos 475
      pos 2100
    doc 18
      freq 1
      pos 92
    skipList 
      level 0
        skipDoc 7
        skipDocFP 242840
        impacts 
          impact 
            freq 1
            norm 100
          impact 
            freq 2
            norm 108
        impactsEnd 
        skipDoc 15
        skipDocFP 243146
        impacts 
          impact 
            freq 1
            norm 95
        impactsEnd 
  term abstracted
    doc 15
      freq 1
      pos 3769
  term ac
    doc 1
      freq 3
      pos 1027
      pos 1028
      pos 4886
    doc 3
      freq 2
      pos 625
      pos 628
    doc 17
      freq 77
      pos 20
      pos 105
      pos 124
      pos 131
      pos 157
      pos 232
      pos 240
      pos 247
      pos 251
      pos 295
      pos 315
      pos 366
      pos 395
      pos 409
      pos 416
      pos 419
      pos 438
      pos 446
      pos 456
      pos 499
      pos 516
      pos 547
      pos 554
      pos 568
      pos 569
      pos 585
      pos 597
      pos 602
      pos 605
      pos 610
      pos 647
      pos 667
      pos 699
      pos 714
      pos 729
      pos 733
      pos 741
      pos 756
      pos 769
      pos 774
      pos 782
      pos 816
      pos 1005
      pos 1054
      pos 1060
      pos 1083
      pos 1088
      pos 1090
      pos 1305
      pos 1340
      pos 1355
      pos 1365
      pos 1369
      pos 1377
      pos 1400
      pos 1516
      pos 1524
      pos 1549
      pos 1596
      pos 1617
      pos 1642
      pos 1674
      pos 1692
      pos 1762
      pos 1804
      pos 1849
      pos 1862
      pos 1886
      pos 1933
      pos 1940
      pos 1946
      pos 1960
      pos 2114
      pos 2152
      pos 2190
      pos 2321
      pos 2407
  term ac's
    doc 17
      freq 1
      pos 1608
  term acc
    doc 13
      freq 7
      pos 6199
      pos 6213
      pos 6234
      pos 6253
      pos 6266
      pos 6296
      pos 6341
  term accept
    doc 1
      freq 5
      pos 4658
      pos 4700
      pos 5591
      pos 7272
      pos 8138
    doc 5
      freq 1
      pos 3444
    doc 7
      freq 2
      pos 1480
      pos 1517
    doc 10
      freq 2
      pos 804
      pos 11074
    doc 11
      freq 28
      pos 517
      pos 2121
      pos 2321
      pos 2504
      pos 2665
      pos 3482
      pos 3533
      pos 3582
      pos 3632
      pos 3728
      pos 3974
      pos 4093
      pos 4121
      pos 5121
      pos 5285
      pos 5814
      pos 6466
      pos 6629
      pos 7123
      pos 7296
      pos 7442
      pos 7455
      pos 7484
      pos 7502
      pos 8968
      pos 8988
      pos 9033
      pos 9088
    doc 15
      freq 1
      pos 3449
    doc 16
      freq 2
      pos 1997
      pos 2365
  term acceptabl
    doc 1
      freq 1
      pos 1797
    doc 6
      freq 3
      pos 2629
      pos 2651
      pos 2654
    doc 9
      freq 1
      pos 457
    doc 10
      freq 1
      pos 3068
    doc 11
      freq 7
      pos 5570
      pos 5736
      pos 5861
      pos 6056
      pos 6128
      pos 6839
      pos 9015
    doc 12
      freq 2
      pos 4639
      pos 6473
    doc 13
      freq 1
      pos 4947
  term accepted
    doc 0
      freq 1
      pos 5844
    doc 1
      freq 2
      pos 8457
      pos 8484
    doc 7
      freq 1
      pos 1632
    doc 11
      freq 1
      pos 9166
    doc 17
      freq 1
      pos 137
  term accepting
    doc 9
      freq 1
      pos 1474
  term accepts
    doc 5
      freq 1
      pos 1340
    doc 11
      freq 5
      pos 5585
      pos 5751
      pos 5884
      pos 6092
      pos 6321
  term access
    doc 0
      freq 305
      pos 2292
      pos 2335
      pos 2388
      pos 2470
      pos 2547
      pos 2616
      pos 2668
      pos 2726
      pos 2773
      pos 2811
      pos 2859
      pos 2952
      pos 2978
      pos 3039
      pos 3138
      pos 3179
      pos 3235
      pos 3356
      pos 3410
      pos 3470
      pos 3525
      pos 3593
      pos 3698
      pos 3721
      pos 3775
      pos 3884
      pos 3927
      pos 3957
      pos 4007
      pos 4101
      pos 4210
      pos 4233
      pos 4287
      pos 4384
      pos 4460
      pos 4481
      pos 4528
      pos 4561
      pos 4587
      pos 4614
      pos 4654
      pos 4674
      pos 4738
      pos 4758
      pos 4827
      pos 4867
      pos 4966
      pos 5031
      pos 5143
      pos 5172
      pos 5202
      pos 5243
      pos 5412
      pos 5435
      pos 5515
      pos 5594
      pos 5627
      pos 5649
      pos 5733
      pos 5792
      pos 5829
      pos 5906
      pos 5957
      pos 6022
      pos 6082
      pos 6136
      pos 6192
      pos 6216
      pos 6278
      pos 6301
      pos 6384
      pos 6404
      pos 6445
      pos 6471
      pos 6505
      pos 6613
      pos 6723
      pos 6784
      pos 6843
      pos 6937
      pos 6984
      pos 7024
      pos 7102
      pos 7159
      pos 7207
      pos 7228
      pos 7289
      pos 7316
      pos 7389
      pos 7422
      pos 7447
      pos 7474
      pos 7504
      pos 7547
      pos 7574
      pos 7618
      pos 7657
      pos 7685
      pos 7718
      pos 7754
      pos 7775
      pos 7846
      pos 7901
      pos 7932
      pos 7969
      pos 8010
      pos 8049
      pos 8090
      pos 8144
      pos 8181
      pos 8215
      pos 8274
      pos 8303
      pos 8368
      pos 8396
      pos 8443
      pos 8511
      pos 8569
      pos 8627
      pos 8684
      pos 8729
      pos 8771
      pos 8818
      pos 8851
      pos 8916
      pos 8978
      pos 9009
      pos 9054
      pos 9099
      pos 9123
      pos 9149
      pos 9179
      pos 9253
      pos 9293
      pos 9323
      pos 9402
      pos 9450
      pos 9501
      pos 9533
      pos 9601
      pos 9633
      pos 9686
      pos 9715
      pos 9756
      pos 9826
      pos 9858
      pos 9918
      pos 9976
      pos 10000
      pos 10076
      pos 10109
      pos 10158
      pos 10199
      pos 10244
      pos 10471
      pos 10508
      pos 10542
      pos 10618
      pos 10716
      pos 10816
      pos 10890
      pos 10923
      pos 11074
      pos 11107
      pos 11152
      pos 11250
      pos 11281
      pos 11315
      pos 11354
      pos 11406
      pos 11457
      pos 11501
      pos 11534
      pos 11564
      pos 11598
      pos 11674
      pos 11714
      pos 11733
      pos 11802
      pos 11823
      pos 11847
      pos 11867
      pos 11901
      pos 11925
      pos 11947
      pos 11966
      pos 12039
      pos 12072
      pos 12129
      pos 12166
      pos 12198
      pos 12220
      pos 12239
      pos 12262
      pos 12303
      pos 12338
      pos 12362
      pos 12387
      pos 12415
      pos 12440
      pos 12478
      pos 12504
      pos 12534
      pos 12578
      pos 12605
      pos 12653
      pos 12674
      pos 12729
      pos 12750
      pos 14825
      pos 14830
      pos 14837
      pos 14842
      pos 14849
      pos 14854
      pos 14861
      pos 14866
      pos 14873
      pos 14878
      pos 14885
      pos 14890
      pos 14897
      pos 14902
      pos 14909
      pos 14914
      pos 14933
      pos 14938
      pos 14945
      pos 14950
      pos 14957
      pos 14962
      pos 14969
      pos 14974
      pos 14981
      pos 14986
      pos 14993
      pos 14998
      pos 15005
      pos 15010
      pos 15017
      pos 15022
      pos 15029
      pos 15034
      pos 15041
      pos 15058
      pos 15065
      pos 15070
      pos 15077
      pos 15082
      pos 15089
      pos 15094
      pos 15101
      pos 15106
      pos 15113
      pos 15118
      pos 15125
      pos 15130
      pos 15137
      pos 15142
      pos 15149
      pos 15154
      pos 15161
      pos 15166
      pos 15185
      pos 15190
      pos 15197
      pos 15202
      pos 15209
      pos 15214
      pos 15221
      pos 15226
      pos 15233
      pos 15238
      pos 15245
      pos 15250
      pos 15257
      pos 15262
      pos 15269
      pos 15274
      pos 15281
      pos 15286
      pos 15293
      pos 15298
      pos 15317
      pos 15322
      pos 15329
      pos 15334
      pos 15341
      pos 15346
      pos 15353
      pos 15358
      pos 15365
      pos 15370
      pos 15377
      pos 15382
      pos 15389
      pos 15394
      pos 16106
      pos 16167
      pos 16682
      pos 16698
      pos 16711
      pos 16785
      pos 16835
      pos 16860
    doc 1
      freq 3
      pos 8020
      pos 8115
      pos 8124
    doc 2
      freq 33
      pos 123
      pos 725
      pos 730
      pos 758
      pos 789
      pos 817
      pos 854
      pos 897
      pos 1982
      pos 2406
      pos 2412
      pos 2469
      pos 2492
      pos 2513
      pos 2544
      pos 2602
      pos 2608
      pos 2643
      pos 2677
      pos 2725
      pos 2732
      pos 3320
      pos 4057
      pos 4092
      pos 5349
      pos 5687
      pos 6053
      pos 6063
      pos 6075
      pos 6092
      pos 6104
      pos 6113
      pos 6248
    doc 3
      freq 5
      pos 4132
      pos 4433
      pos 4439
      pos 4477
      pos 4483
    doc 6
      freq 1
      pos 2601
    doc 7
      freq 1
      pos 366
    doc 10
      freq 1
      pos 2191
    doc 12
      freq 1
      pos 4984
    doc 13
      freq 22
      pos 319
      pos 895
      pos 1021
      pos 1294
      pos 1318
      pos 2211
      pos 2252
      pos 2271
      pos 2368
      pos 2660
      pos 2817
      pos 3142
      pos 3745
      pos 4078
      pos 4094
      pos 4356
      pos 6136
      pos 6148
      pos 6191
      pos 6208
      pos 6221
      pos 6260
    doc 16
      freq 6
      pos 21
      pos 94
      pos 183
      pos 2527
      pos 2550
      pos 2596
    doc 18
      freq 1
      pos 1663
    skipList 
      level 0
        skipDoc 12
        skipDocFP 247114
        impacts 
          impact 
            freq 1
            norm 100
          impact 
            freq 5
            norm 107
          impact 
            freq 33
            norm 108
          impact 
            freq 305
            norm 120
        impactsEnd 
  term accessed
    doc 0
      freq 5
      pos 225
      pos 242
      pos 3654
      pos 4170
      pos 11012
    doc 15
      freq 1
      pos 1935
  term accessibl
    doc 0
      freq 80
      pos 3041
      pos 3140
      pos 3181
      pos 3358
      pos 3412
      pos 3527
      pos 3595
      pos 3700
      pos 3723
      pos 3777
      pos 4009
      pos 4103
      pos 4212
      pos 4235
      pos 4289
      pos 4462
      pos 4483
      pos 4530
      pos 4563
      pos 4656
      pos 4676
      pos 4740
      pos 5414
      pos 5437
      pos 5517
      pos 6280
      pos 6303
      pos 6386
      pos 7209
      pos 7230
      pos 7291
      pos 7756
      pos 7777
      pos 7848
      pos 8276
      pos 8305
      pos 8370
      pos 8398
      pos 8820
      pos 8853
      pos 8918
      pos 9404
      pos 9452
      pos 9503
      pos 9603
      pos 9635
      pos 9688
      pos 9828
      pos 9860
      pos 9978
      pos 10002
      pos 10078
      pos 10892
      pos 10925
      pos 11076
      pos 11109
      pos 11154
      pos 11252
      pos 11716
      pos 11735
      pos 11804
      pos 11825
      pos 12041
      pos 12074
      pos 12131
      pos 12304
      pos 12339
      pos 12363
      pos 12388
      pos 12416
      pos 12441
      pos 12479
      pos 12505
      pos 12535
      pos 12579
      pos 12606
      pos 12654
      pos 12675
      pos 12730
      pos 12751
    doc 13
      freq 1
      pos 6185
    doc 18
      freq 1
      pos 1675
  term accessing
    doc 13
      freq 2
      pos 84
      pos 6131
  term accommodat
    doc 6
      freq 2
      pos 1511
      pos 2206
    doc 13
      freq 1
      pos 717
  term accommodated
    doc 14
      freq 1
      pos 2559
  term accommodating
    doc 2
      freq 1
      pos 3967
  term accompanied
    doc 12
      freq 1
      pos 5107
  term accompanying
    doc 1
      freq 1
      pos 558
  term accomplish
    doc 10
      freq 1
      pos 4556
  term accomplished
    doc 1
      freq 1
      pos 5630
    doc 2
      freq 1
      pos 6154
    doc 14
      freq 1
      pos 2185
  term accordanc
    doc 10
      freq 1
      pos 3950
    doc 17
      freq 2
      pos 590
      pos 689
  term according
    doc 0
      freq 2
      pos 5355
      pos 10344
    doc 1
      freq 1
      pos 1998
    doc 3
      freq 2
      pos 1704
      pos 1852
    doc 4
      freq 1
      pos 1196
    doc 5
      freq 1
      pos 1080
    doc 8
      freq 3
      pos 242
      pos 255
      pos 394
    doc 9
      freq 1
      pos 1099
    doc 13
      freq 2
      pos 1011
      pos 4400
    doc 16
      freq 1
      pos 842
    doc 18
      freq 1
      pos 667
    skipList 
      level 0
        skipDoc 13
        skipDocFP 255775
        impacts 
          impact 
            freq 1
            norm 95
          impact 
            freq 3
            norm 97
        impactsEnd 
  term accordingly
    doc 10
      freq 17
      pos 1101
      pos 1530
      pos 1754
      pos 3565
      pos 4324
      pos 5871
      pos 6565
      pos 7072
      pos 7165
      pos 7192
      pos 7283
      pos 7591
      pos 7898
      pos 9433
      pos 10145
      pos 10231
      pos 10287
    doc 13
      freq 1
      pos 2401
    doc 14
      freq 1
      pos 409
  term account
    doc 2
      freq 1
      pos 598
    doc 7
      freq 1
      pos 1554
    doc 15
      freq 1
      pos 2954
    doc 18
      freq 1
      pos 1565
  term accounting
    doc 2
      freq 4
      pos 83
      pos 230
      pos 3041
      pos 3055
  term accounts
    doc 10
      freq 3
      pos 2829
      pos 9700
      pos 13039
  term accumulated
    doc 0
      freq 1
      pos 14355
  term accurat
    doc 10
      freq 3
      pos 640
      pos 3156
      pos 3163
    doc 11
      freq 1
      pos 758
  term accurately
    doc 10
      freq 1
      pos 4422
    doc 13
      freq 1
      pos 2185
  term acebdcmyb
    doc 11
      freq 1
      pos 10042
  term achiev
    doc 3
      freq 1
      pos 1466
    doc 4
      freq 1
      pos 346
    doc 12
      freq 2
      pos 6733
      pos 7983
    doc 13
      freq 1
      pos 5250
  term achieved
    doc 3
      freq 4
      pos 1486
      pos 1531
      pos 3594
      pos 4130
    doc 4
      freq 3
      pos 4060
      pos 4165
      pos 4216
    doc 12
      freq 1
      pos 2301
    doc 13
      freq 2
      pos 2391
      pos 4590
  term achieves
    doc 13
      freq 1
      pos 4310
  term acjj3mv5mg
    doc 10
      freq 1
      pos 12623
  term ack
    doc 10
      freq 2
      pos 5787
      pos 5817
  term acknowledg
    doc 1
      freq 1
      pos 8876
    doc 2
      freq 1
      pos 3458
    doc 6
      freq 1
      pos 3091
  term acknowledgement
    doc 0
      freq 1
      pos 17526
    doc 1
      freq 1
      pos 9907
    doc 2
      freq 1
      pos 6704
    doc 3
      freq 1
      pos 6256
    doc 4
      freq 1
      pos 6411
    doc 5
      freq 1
      pos 4741
    doc 6
      freq 1
      pos 3541
    doc 7
      freq 1
      pos 3246
    doc 8
      freq 1
      pos 2463
    doc 9
      freq 4
      pos 137
      pos 709
      pos 1621
      pos 2108
    doc 10
      freq 1
      pos 13769
    doc 11
      freq 1
      pos 10930
    doc 12
      freq 1
      pos 9780
    doc 13
      freq 1
      pos 7395
    doc 14
      freq 1
      pos 5861
    doc 15
      freq 1
      pos 4380
    doc 16
      freq 1
      pos 2991
    doc 17
      freq 1
      pos 2715
    doc 18
      freq 1
      pos 2503
    skipList 
      level 0
        skipDoc 7
        skipDocFP 258290
        impacts 
          impact 
            freq 1
            norm 100
        impactsEnd 
        skipDoc 15
        skipDocFP 258595
        impacts 
          impact 
            freq 4
            norm 95
        impactsEnd 
  term acknowledgements
    doc 0
      freq 2
      pos 166
      pos 15838
    doc 1
      freq 2
      pos 397
      pos 8871
    doc 2
      freq 2
      pos 163
      pos 3452
    doc 4
      freq 2
      pos 271
      pos 5450
    doc 5
      freq 2
      pos 332
      pos 4064
    doc 6
      freq 1
      pos 3087
    doc 7
      freq 2
      pos 149
      pos 1765
    doc 10
      freq 2
      pos 359
      pos 12102
    doc 11
      freq 2
      pos 536
      pos 9422
    doc 12
      freq 2
      pos 430
      pos 6746
    doc 13
      freq 2
      pos 344
      pos 6953
    doc 14
      freq 2
      pos 269
      pos 5336
    doc 15
      freq 2
      pos 291
      pos 3831
    doc 16
      freq 1
      pos 1576
    doc 18
      freq 2
      pos 177
      pos 1996
    skipList 
      level 0
        skipDoc 10
        skipDocFP 259395
        impacts 
          impact 
            freq 2
            norm 100
        impactsEnd 
  term acont
    doc 4
      freq 1
      pos 6056
  term acp
    doc 17
      freq 9
      pos 362
      pos 389
      pos 705
      pos 922
      pos 992
      pos 1290
      pos 1311
      pos 1348
      pos 2352
  term acpolicies
    doc 17
      freq 4
      pos 507
      pos 523
      pos 2169
      pos 2288
  term acpoliciessyntax
    doc 17
      freq 2
      pos 786
      pos 2294
  term acpolicyid
    doc 17
      freq 4
      pos 796
      pos 805
      pos 2304
      pos 2326
  term acps
    doc 17
      freq 14
      pos 97
      pos 148
      pos 844
      pos 860
      pos 913
      pos 917
      pos 1001
      pos 1011
      pos 1023
      pos 1275
      pos 1362
      pos 2271
      pos 2343
      pos 2347
  term acpsur
    doc 17
      freq 2
      pos 920
      pos 2350
  term acquir
    doc 10
      freq 4
      pos 1636
      pos 2011
      pos 3930
      pos 6736
    doc 15
      freq 2
      pos 389
      pos 666
  term acquired
    doc 10
      freq 3
      pos 3352
      pos 4106
      pos 10407
  term acquiring
    doc 10
      freq 1
      pos 4038
  term acquisition
    doc 10
      freq 1
      pos 5703
  term across
    doc 0
      freq 1
      pos 6249
    doc 1
      freq 1
      pos 1208
    doc 2
      freq 1
      pos 2415
    doc 3
      freq 8
      pos 1115
      pos 1283
      pos 1304
      pos 1379
      pos 1443
      pos 1513
      pos 2619
      pos 3186
    doc 8
      freq 1
      pos 1695
    doc 10
      freq 1
      pos 1722
    doc 12
      freq 1
      pos 5487
    doc 13
      freq 3
      pos 938
      pos 5308
      pos 5670
    skipList 
      level 0
        skipDoc 13
        skipDocFP 261488
        impacts 
          impact 
            freq 1
            norm 97
          impact 
            freq 8
            norm 107
        impactsEnd 
  term acs
    doc 3
      freq 2
      pos 1334
      pos 1344
    doc 17
      freq 7
      pos 339
      pos 1322
      pos 1332
      pos 1424
      pos 1431
      pos 1600
      pos 1791
  term act
    doc 0
      freq 2
      pos 5982
      pos 6034
    doc 1
      freq 1
      pos 6626
    doc 10
      freq 6
      pos 1649
      pos 2239
      pos 4725
      pos 7795
      pos 7912
      pos 10281
    doc 11
      freq 1
      pos 8006
    doc 15
      freq 1
      pos 2208
  term acted
    doc 2
      freq 1
      pos 4482
  term acting
    doc 4
      freq 1
      pos 4621
    doc 10
      freq 1
      pos 3911
  term action
    doc 0
      freq 1
      pos 752
    doc 1
      freq 2
      pos 6768
      pos 6977
    doc 4
      freq 1
      pos 5019
    doc 17
      freq 1
      pos 1983
  term actions
    doc 4
      freq 3
      pos 4137
      pos 4185
      pos 4350
    doc 6
      freq 1
      pos 2786
    doc 9
      freq 1
      pos 418
  term activ
    doc 0
      freq 13
      pos 3067
      pos 3099
      pos 3114
      pos 3201
      pos 3290
      pos 3311
      pos 3918
      pos 4430
      pos 4890
      pos 4902
      pos 5714
      pos 10149
      pos 11448
    doc 1
      freq 1
      pos 4996
    doc 2
      freq 2
      pos 3736
      pos 5397
    doc 3
      freq 1
      pos 3497
    doc 7
      freq 1
      pos 1795
    doc 10
      freq 1
      pos 8731
    doc 13
      freq 2
      pos 2458
      pos 3280
  term actively
    doc 7
      freq 1
      pos 669
    doc 18
      freq 1
      pos 520
  term activities
    doc 2
      freq 1
      pos 2822
    doc 13
      freq 1
      pos 538
  term activity
    doc 0
      freq 1
      pos 17540
    doc 1
      freq 1
      pos 9921
    doc 2
      freq 1
      pos 6718
    doc 3
      freq 1
      pos 6270
    doc 4
      freq 1
      pos 6425
    doc 5
      freq 1
      pos 4755
    doc 6
      freq 1
      pos 3555
    doc 7
      freq 1
      pos 3260
    doc 8
      freq 1
      pos 2477
    doc 9
      freq 1
      pos 2122
    doc 10
      freq 1
      pos 13783
    doc 11
      freq 1
      pos 10944
    doc 12
      freq 1
      pos 9794
    doc 13
      freq 1
      pos 7409
    doc 14
      freq 2
      pos 2741
      pos 5875
    doc 15
      freq 1
      pos 4394
    doc 16
      freq 1
      pos 3005
    doc 17
      freq 1
      pos 2729
    doc 18
      freq 1
      pos 2517
    skipList 
      level 0
        skipDoc 7
        skipDocFP 263816
        impacts 
          impact 
            freq 1
            norm 100
        impactsEnd 
        skipDoc 15
        skipDocFP 264121
        impacts 
          impact 
            freq 1
            norm 95
          impact 
            freq 2
            norm 107
        impactsEnd 
  term acts
    doc 1
      freq 1
      pos 5188
    doc 10
      freq 2
      pos 2221
      pos 10521
  term actual
    doc 1
      freq 1
      pos 5935
    doc 3
      freq 1
      pos 3466
    doc 4
      freq 1
      pos 4625
    doc 5
      freq 2
      pos 556
      pos 2271
    doc 11
      freq 2
      pos 4363
      pos 5919
    doc 13
      freq 1
      pos 4910
  term actually
    doc 1
      freq 1
      pos 8276
    doc 5
      freq 1
      pos 1498
    doc 11
      freq 1
      pos 6078
    doc 12
      freq 4
      pos 2247
      pos 3796
      pos 5392
      pos 7946
    doc 13
      freq 1
      pos 6190
    doc 17
      freq 1
      pos 1817
    doc 18
      freq 1
      pos 1970
  term acunotic
    doc 17
      freq 5
      pos 852
      pos 885
      pos 916
      pos 2279
      pos 2346
  term acusernotic
    doc 17
      freq 2
      pos 927
      pos 2357
  term ad2005
    doc 12
      freq 2
      pos 6552
      pos 7658
  term adam
    doc 10
      freq 1
      pos 12127
    doc 11
      freq 1
      pos 9488
  term adaptation
    doc 3
      freq 3
      pos 312
      pos 1065
      pos 5598
  term adapting
    doc 3
      freq 1
      pos 2668
  term adc0uro29zmr5blx4bbnoietlueqlrevccd2zeyg
    doc 11
      freq 1
      pos 10191
  term add
    doc 0
      freq 2
      pos 1191
      pos 15892
    doc 2
      freq 1
      pos 3824
    doc 3
      freq 3
      pos 2749
      pos 5084
      pos 5100
    doc 10
      freq 12
      pos 2245
      pos 2276
      pos 2490
      pos 3309
      pos 3334
      pos 3644
      pos 6585
      pos 7076
      pos 7100
      pos 7301
      pos 9239
      pos 10319
    doc 12
      freq 1
      pos 4365
    doc 16
      freq 1
      pos 479
    doc 18
      freq 1
      pos 1281
  term add2
    doc 0
      freq 1
      pos 10353
  term added
    doc 2
      freq 2
      pos 5094
      pos 6168
    doc 3
      freq 3
      pos 2812
      pos 2814
      pos 3901
    doc 4
      freq 15
      pos 5601
      pos 5606
      pos 5650
      pos 5680
      pos 5690
      pos 5727
      pos 5740
      pos 5828
      pos 5855
      pos 5875
      pos 5893
      pos 5902
      pos 5952
      pos 5961
      pos 6012
    doc 5
      freq 5
      pos 1629
      pos 3819
      pos 3857
      pos 3886
      pos 4034
    doc 10
      freq 10
      pos 3325
      pos 6599
      pos 7315
      pos 11511
      pos 11611
      pos 11706
      pos 11807
      pos 11901
      pos 12293
      pos 12972
    doc 12
      freq 5
      pos 1961
      pos 2321
      pos 2325
      pos 2533
      pos 2583
    doc 13
      freq 1
      pos 4722
    doc 16
      freq 1
      pos 1676
    doc 18
      freq 1
      pos 1939
    skipList 
      level 0
        skipDoc 16
        skipDocFP 266764
        impacts 
          impact 
            freq 1
            norm 99
          impact 
            freq 5
            norm 104
          impact 
            freq 15
            norm 108
        impactsEnd 
  term adding
    doc 1
      freq 1
      pos 1488
    doc 3
      freq 2
      pos 997
      pos 5168
    doc 10
      freq 3
      pos 8996
      pos 12928
      pos 12949
    doc 12
      freq 6
      pos 276
      pos 2513
      pos 2604
      pos 4311
      pos 4341
      pos 5029
    doc 13
      freq 1
      pos 2273
    doc 15
      freq 1
      pos 1721
  term addition
    doc 1
      freq 3
      pos 1873
      pos 2950
      pos 8724
    doc 2
      freq 2
      pos 5060
      pos 5722
    doc 3
      freq 1
      pos 482
    doc 9
      freq 1
      pos 278
    doc 12
      freq 2
      pos 2577
      pos 8891
    doc 13
      freq 3
      pos 3110
      pos 3452
      pos 5801
    doc 16
      freq 1
      pos 368
    doc 18
      freq 2
      pos 2006
      pos 2035
    skipList 
      level 0
        skipDoc 18
        skipDocFP 268295
        impacts 
          impact 
            freq 1
            norm 95
          impact 
            freq 2
            norm 97
          impact 
            freq 3
            norm 109
        impactsEnd 
  term additional
    doc 0
      freq 3
      pos 372
      pos 16309
      pos 16705
    doc 1
      freq 4
      pos 408
      pos 551
      pos 816
      pos 9182
    doc 2
      freq 5
      pos 1881
      pos 4459
      pos 5736
      pos 5760
      pos 6172
    doc 3
      freq 5
      pos 1213
      pos 3244
      pos 3255
      pos 3941
      pos 4145
    doc 4
      freq 2
      pos 366
      pos 659
    doc 5
      freq 3
      pos 2244
      pos 2455
      pos 4381
    doc 7
      freq 1
      pos 1133
    doc 10
      freq 7
      pos 1736
      pos 2666
      pos 5283
      pos 5753
      pos 8080
      pos 8255
      pos 9407
    doc 11
      freq 4
      pos 794
      pos 3746
      pos 4233
      pos 4246
    doc 12
      freq 55
      pos 300
      pos 307
      pos 460
      pos 471
      pos 478
      pos 745
      pos 970
      pos 1035
      pos 2872
      pos 2880
      pos 2888
      pos 2898
      pos 2932
      pos 3047
      pos 3070
      pos 3076
      pos 3512
      pos 3587
      pos 5043
      pos 6793
      pos 7636
      pos 8077
      pos 8110
      pos 8116
      pos 8124
      pos 8128
      pos 8144
      pos 8173
      pos 8184
      pos 8199
      pos 8290
      pos 8343
      pos 8360
      pos 8371
      pos 8392
      pos 8433
      pos 8448
      pos 8467
      pos 8539
      pos 8545
      pos 8559
      pos 8645
      pos 8655
      pos 8775
      pos 8844
      pos 8855
      pos 8953
      pos 8980
      pos 9020
      pos 9072
      pos 9084
      pos 9108
      pos 9286
      pos 9350
      pos 9385
    doc 13
      freq 1
      pos 2255
    doc 14
      freq 3
      pos 2258
      pos 2447
      pos 2816
    doc 15
      freq 3
      pos 1723
      pos 2354
      pos 3298
    doc 17
      freq 2
      pos 119
      pos 344
    skipList 
      level 0
        skipDoc 10
        skipDocFP 269004
        impacts 
          impact 
            freq 1
            norm 100
          impact 
            freq 3
            norm 104
          impact 
            freq 5
            norm 107
          impact 
            freq 7
            norm 116
        impactsEnd 
  term additionally
    doc 1
      freq 1
      pos 2312
    doc 5
      freq 3
      pos 1534
      pos 3128
      pos 4084
    doc 8
      freq 4
      pos 593
      pos 971
      pos 1265
      pos 1460
    doc 14
      freq 1
      pos 1904
    doc 16
      freq 1
      pos 971
  term additions
    doc 2
      freq 1
      pos 4691
  term addr
    doc 4
      freq 2
      pos 407
      pos 5329
    doc 10
      freq 12
      pos 3018
      pos 4918
      pos 4947
      pos 5164
      pos 5326
      pos 5328
      pos 5337
      pos 5346
      pos 5359
      pos 5373
      pos 7177
      pos 7885
    doc 11
      freq 7
      pos 341
      pos 348
      pos 1689
      pos 6257
      pos 6285
      pos 6385
      pos 6393
    doc 12
      freq 1
      pos 7852
  term address
    doc 0
      freq 107
      pos 411
      pos 835
      pos 843
      pos 859
      pos 869
      pos 1066
      pos 1347
      pos 1418
      pos 3029
      pos 3149
      pos 3189
      pos 3318
      pos 3324
      pos 3421
      pos 3478
      pos 3489
      pos 3493
      pos 3554
      pos 3573
      pos 3576
      pos 3605
      pos 3708
      pos 3712
      pos 3729
      pos 3734
      pos 3736
      pos 3748
      pos 3757
      pos 3790
      pos 3896
      pos 3940
      pos 3971
      pos 4114
      pos 4220
      pos 4224
      pos 4241
      pos 4246
      pos 4251
      pos 4262
      pos 4274
      pos 4302
      pos 4396
      pos 7485
      pos 8109
      pos 9062
      pos 9371
      pos 9377
      pos 9461
      pos 9541
      pos 9557
      pos 9563
      pos 9644
      pos 9726
      pos 9764
      pos 9778
      pos 9940
      pos 9944
      pos 9953
      pos 9956
      pos 9990
      pos 10012
      pos 10017
      pos 10121
      pos 10182
      pos 10210
      pos 10214
      pos 10261
      pos 10272
      pos 10334
      pos 10365
      pos 10408
      pos 10432
      pos 10550
      pos 10567
      pos 10572
      pos 10598
      pos 10604
      pos 10637
      pos 10668
      pos 10676
      pos 10735
      pos 10758
      pos 10761
      pos 10826
      pos 10861
      pos 10871
      pos 10935
      pos 10945
      pos 10962
      pos 11086
      pos 11119
      pos 11124
      pos 11126
      pos 11129
      pos 11134
      pos 11166
      pos 11294
      pos 11332
      pos 11366
      pos 11418
      pos 11470
      pos 11606
      pos 11625
      pos 12759
      pos 13708
      pos 17196
      pos 17516
    doc 1
      freq 10
      pos 3197
      pos 4333
      pos 8489
      pos 8522
      pos 8575
      pos 8586
      pos 8605
      pos 8620
      pos 8665
      pos 9897
    doc 2
      freq 8
      pos 2978
      pos 4899
      pos 5085
      pos 6088
      pos 6097
      pos 6144
      pos 6375
      pos 6694
    doc 3
      freq 4
      pos 456
      pos 458
      pos 3387
      pos 6246
    doc 4
      freq 65
      pos 168
      pos 1060
      pos 1095
      pos 1101
      pos 1127
      pos 1135
      pos 1150
      pos 1156
      pos 1159
      pos 1167
      pos 1177
      pos 1186
      pos 1192
      pos 1208
      pos 1220
      pos 1243
      pos 1669
      pos 1788
      pos 1800
      pos 1804
      pos 1807
      pos 1819
      pos 2152
      pos 2157
      pos 2184
      pos 2186
      pos 2193
      pos 2258
      pos 2380
      pos 2399
      pos 2408
      pos 2418
      pos 2424
      pos 2441
      pos 2477
      pos 2482
      pos 2525
      pos 2612
      pos 2818
      pos 2823
      pos 2944
      pos 2955
      pos 3063
      pos 3068
      pos 3299
      pos 3304
      pos 3592
      pos 3596
      pos 3763
      pos 3768
      pos 3867
      pos 3888
      pos 3914
      pos 3920
      pos 3928
      pos 4246
      pos 4442
      pos 5090
      pos 5109
      pos 5695
      pos 5697
      pos 5787
      pos 5801
      pos 5980
      pos 6401
    doc 5
      freq 2
      pos 563
      pos 4731
    doc 6
      freq 2
      pos 794
      pos 3531
    doc 7
      freq 3
      pos 2454
      pos 2466
      pos 3236
    doc 8
      freq 2
      pos 2128
      pos 2453
    doc 9
      freq 11
      pos 198
      pos 209
      pos 286
      pos 494
      pos 804
      pos 886
      pos 1211
      pos 1484
      pos 1491
      pos 1763
      pos 2098
    doc 10
      freq 13
      pos 442
      pos 1020
      pos 1065
      pos 1128
      pos 1148
      pos 1161
      pos 1808
      pos 1986
      pos 3452
      pos 7182
      pos 7472
      pos 8362
      pos 13759
    doc 11
      freq 3
      pos 2332
      pos 8435
      pos 10920
    doc 12
      freq 67
      pos 393
      pos 637
      pos 770
      pos 1242
      pos 1361
      pos 1388
      pos 1411
      pos 1463
      pos 1535
      pos 1589
      pos 1595
      pos 1603
      pos 2545
      pos 2556
      pos 2638
      pos 3427
      pos 3437
      pos 3591
      pos 3885
      pos 3902
      pos 4246
      pos 4303
      pos 4431
      pos 4437
      pos 4451
      pos 4754
      pos 4829
      pos 4869
      pos 4885
      pos 4939
      pos 4979
      pos 5024
      pos 5035
      pos 5070
      pos 5091
      pos 5164
      pos 5432
      pos 5458
      pos 5492
      pos 5510
      pos 5537
      pos 5569
      pos 5587
      pos 5642
      pos 5657
      pos 5699
      pos 5723
      pos 5736
      pos 5827
      pos 5837
      pos 5927
      pos 5948
      pos 6030
      pos 6065
      pos 6119
      pos 6155
      pos 6171
      pos 6419
      pos 6467
      pos 6584
      pos 6872
      pos 7080
      pos 7133
      pos 7478
      pos 7617
      pos 8062
      pos 9770
    doc 13
      freq 1
      pos 7385
    doc 14
      freq 1
      pos 5851
    doc 15
      freq 13
      pos 390
      pos 397
      pos 620
      pos 623
      pos 655
      pos 1609
      pos 1614
      pos 2515
      pos 2548
      pos 2770
      pos 2786
      pos 3917
      pos 4370
    doc 16
      freq 2
      pos 2649
      pos 2981
    doc 17
      freq 1
      pos 2705
    doc 18
      freq 1
      pos 2493
    skipList 
      level 0
        skipDoc 7
        skipDocFP 271920
        impacts 
          impact 
            freq 3
            norm 100
          impact 
            freq 4
            norm 107
          impact 
            freq 65
            norm 108
          impact 
            freq 107
            norm 120
        impactsEnd 
        skipDoc 15
        skipDocFP 275160
        impacts 
          impact 
            freq 11
            norm 95
          impact 
            freq 13
            norm 104
          impact 
            freq 67
            norm 113
        impactsEnd 
  term addressed
    doc 2
      freq 1
      pos 5481
    doc 13
      freq 2
      pos 1540
      pos 4917
  term addresses
    doc 0
      freq 44
      pos 498
      pos 521
      pos 532
      pos 768
      pos 786
      pos 831
      pos 2409
      pos 3050
      pos 3335
      pos 3369
      pos 3500
      pos 3536
      pos 3986
      pos 4048
      pos 4119
      pos 9384
      pos 9415
      pos 9570
      pos 9614
      pos 9701
      pos 9986
      pos 10095
      pos 10313
      pos 10901
      pos 12451
      pos 13211
      pos 14462
      pos 14469
      pos 14486
      pos 14493
      pos 14522
      pos 14529
      pos 14628
      pos 14635
      pos 14652
      pos 14659
      pos 14688
      pos 14695
      pos 14712
      pos 14719
      pos 14736
      pos 14743
      pos 15760
      pos 17123
    doc 1
      freq 2
      pos 8516
      pos 9504
    doc 3
      freq 2
      pos 4136
      pos 5868
    doc 4
      freq 6
      pos 1078
      pos 1124
      pos 2542
      pos 4272
      pos 5670
      pos 6043
    doc 5
      freq 1
      pos 4397
    doc 6
      freq 2
      pos 562
      pos 3179
    doc 7
      freq 2
      pos 2046
      pos 2897
    doc 9
      freq 1
      pos 340
    doc 10
      freq 2
      pos 1332
      pos 13404
    doc 11
      freq 1
      pos 10525
    doc 12
      freq 52
      pos 84
      pos 154
      pos 190
      pos 195
      pos 199
      pos 203
      pos 590
      pos 750
      pos 759
      pos 968
      pos 1235
      pos 1255
      pos 1267
      pos 1280
      pos 1291
      pos 1297
      pos 1324
      pos 1326
      pos 1335
      pos 1398
      pos 2077
      pos 2252
      pos 3377
      pos 3735
      pos 4229
      pos 4466
      pos 4475
      pos 4503
      pos 4524
      pos 4706
      pos 4784
      pos 4791
      pos 4798
      pos 5870
      pos 5883
      pos 6036
      pos 6092
      pos 7214
      pos 7323
      pos 7381
      pos 7418
      pos 7549
      pos 7765
      pos 7902
      pos 7911
      pos 7924
      pos 7929
      pos 7949
      pos 7994
      pos 8011
      pos 8047
      pos 9427
    doc 13
      freq 6
      pos 415
      pos 525
      pos 1629
      pos 1981
      pos 5778
      pos 6988
    doc 14
      freq 1
      pos 5506
    doc 15
      freq 23
      pos 275
      pos 670
      pos 932
      pos 1546
      pos 1571
      pos 1631
      pos 1659
      pos 2069
      pos 2336
      pos 2383
      pos 2449
      pos 2488
      pos 2544
      pos 2798
      pos 2812
      pos 2819
      pos 2932
      pos 2942
      pos 2956
      pos 2975
      pos 3209
      pos 3711
      pos 4015
    doc 16
      freq 1
      pos 384
    doc 17
      freq 1
      pos 2366
    doc 18
      freq 1
      pos 2158
    skipList 
      level 0
        skipDoc 9
        skipDocFP 277864
        impacts 
          impact 
            freq 1
            norm 95
          impact 
            freq 2
            norm 100
          impact 
            freq 6
            norm 108
          impact 
            freq 44
            norm 120
        impactsEnd 
        skipDoc 17
        skipDocFP 278964
        impacts 
          impact 
            freq 1
            norm 98
          impact 
            freq 23
            norm 104
          impact 
            freq 52
            norm 113
        impactsEnd 
  term addressing
    doc 0
      freq 3
      pos 10390
      pos 10417
      pos 10456
    doc 3
      freq 1
      pos 368
    doc 4
      freq 2
      pos 404
      pos 5340
    doc 12
      freq 5
      pos 451
      pos 741
      pos 1258
      pos 7432
      pos 7896
  term addressprefix
    doc 0
      freq 1
      pos 10226
  term adds
    doc 10
      freq 4
      pos 5772
      pos 6424
      pos 7028
      pos 8195
  term adelph
    doc 6
      freq 1
      pos 3147
  term adequat
    doc 0
      freq 1
      pos 16755
    doc 6
      freq 2
      pos 1123
      pos 1374
    doc 10
      freq 1
      pos 10852
    doc 17
      freq 1
      pos 708
  term adequately
    doc 13
      freq 1
      pos 4086
  term adjacencies
    doc 0
      freq 8
      pos 447
      pos 736
      pos 7941
      pos 8839
      pos 8945
      pos 16276
      pos 16290
      pos 17167
    doc 1
      freq 1
      pos 1258
  term adjacency
    doc 0
      freq 38
      pos 729
      pos 6629
      pos 6645
      pos 6668
      pos 7875
      pos 7912
      pos 7997
      pos 8021
      pos 8796
      pos 8799
      pos 8862
      pos 8940
      pos 8959
      pos 8988
      pos 9020
      pos 9188
      pos 9211
      pos 9220
      pos 9266
      pos 9331
      pos 9358
      pos 9369
      pos 9375
      pos 9555
      pos 9561
      pos 9792
      pos 9798
      pos 12665
      pos 13810
      pos 14213
      pos 14243
      pos 14521
      pos 14687
      pos 15586
      pos 16218
      pos 16247
      pos 16260
      pos 16298
  term adjacencystat
    doc 0
      freq 1
      pos 8991
  term adjacencyusag
    doc 0
      freq 1
      pos 9227
  term adjacent
    doc 0
      freq 3
      pos 1334
      pos 12619
      pos 14233
    doc 1
      freq 1
      pos 888
  term adjust
    doc 11
      freq 1
      pos 6118
  term adjusted
    doc 13
      freq 1
      pos 3051
  term administered
    doc 9
      freq 1
      pos 404
    doc 15
      freq 1
      pos 1117
  term administration
    doc 9
      freq 1
      pos 1231
  term administrativ
    doc 0
      freq 5
      pos 2733
      pos 5634
      pos 10177
      pos 11464
      pos 17538
    doc 1
      freq 3
      pos 6234
      pos 8123
      pos 9919
    doc 2
      freq 1
      pos 6716
    doc 3
      freq 1
      pos 6268
    doc 4
      freq 2
      pos 2348
      pos 6423
    doc 5
      freq 1
      pos 4753
    doc 6
      freq 1
      pos 3553
    doc 7
      freq 1
      pos 3258
    doc 8
      freq 1
      pos 2475
    doc 9
      freq 1
      pos 2120
    doc 10
      freq 7
      pos 1440
      pos 2833
      pos 7735
      pos 9660
      pos 11041
      pos 11050
      pos 13781
    doc 11
      freq 1
      pos 10942
    doc 12
      freq 2
      pos 6320
      pos 9792
    doc 13
      freq 1
      pos 7407
    doc 14
      freq 1
      pos 5873
    doc 15
      freq 9
      pos 222
      pos 278
      pos 525
      pos 1104
      pos 1161
      pos 1348
      pos 3051
      pos 3058
      pos 4392
    doc 16
      freq 1
      pos 3003
    doc 17
      freq 1
      pos 2727
    doc 18
      freq 1
      pos 2515
    skipList 
      level 0
        skipDoc 7
        skipDocFP 283156
        impacts 
          impact 
            freq 1
            norm 100
          impact 
            freq 2
            norm 108
          impact 
            freq 3
            norm 113
          impact 
            freq 5
            norm 120
        impactsEnd 
        skipDoc 15
        skipDocFP 283568
        impacts 
          impact 
            freq 1
            norm 95
          impact 
            freq 9
            norm 104
        impactsEnd 
  term administratively
    doc 0
      freq 1
      pos 4972
    doc 1
      freq 2
      pos 4831
      pos 4849
    doc 3
      freq 2
      pos 1801
      pos 1879
    doc 4
      freq 1
      pos 2177
    doc 15
      freq 1
      pos 412
  term administrator
    doc 0
      freq 3
      pos 3549
      pos 4927
      pos 6108
    doc 5
      freq 1
      pos 677
    doc 10
      freq 2
      pos 990
      pos 10685
    doc 12
      freq 4
      pos 4899
      pos 5003
      pos 5460
      pos 9296
    doc 14
      freq 1
      pos 2688
    doc 15
      freq 2
      pos 1588
      pos 2222
  term administrators
    doc 10
      freq 1
      pos 10730
    doc 12
      freq 1
      pos 9376
    doc 15
      freq 1
      pos 1897
    doc 18
      freq 1
      pos 1881
  term admitted
    doc 6
      freq 1
      pos 376
  term adopt
    doc 15
      freq 1
      pos 3607
  term adopted
    doc 3
      freq 1
      pos 5652
    doc 12
      freq 1
      pos 6038
  term adrang
    doc 2
      freq 1
      pos 2301
  term adrian
    doc 0
      freq 1
      pos 15923
  term advanc
    doc 2
      freq 1
      pos 5569
    doc 13
      freq 1
      pos 3532
    doc 18
      freq 1
      pos 592
  term advanced
    doc 7
      freq 1
      pos 189
  term advancement
    doc 7
      freq 1
      pos 1320
  term advances
    doc 17
      freq 1
      pos 1680
  term advantag
    doc 5
      freq 2
      pos 2215
      pos 2448
    doc 9
      freq 1
      pos 479
    doc 15
      freq 1
      pos 1157
  term advent
    doc 12
      freq 1
      pos 4243
  term adversaries
    doc 0
      freq 1
      pos 16034
  term adversary
    doc 5
      freq 8
      pos 2997
      pos 3179
      pos 3206
      pos 3288
      pos 3314
      pos 3385
      pos 3408
      pos 3563
    doc 10
      freq 1
      pos 9963
  term advertis
    doc 0
      freq 1
      pos 12559
    doc 1
      freq 3
      pos 7417
      pos 7615
      pos 7649
    doc 13
      freq 1
      pos 3285
  term advertised
    doc 0
      freq 1
      pos 12546
    doc 1
      freq 2
      pos 4226
      pos 4989
    doc 13
      freq 2
      pos 3251
      pos 3259
  term advertisement
    doc 0
      freq 1
      pos 16337
    doc 1
      freq 3
      pos 4232
      pos 5858
      pos 7716
    doc 7
      freq 2
      pos 763
      pos 2153
    doc 12
      freq 2
      pos 3910
      pos 7732
    doc 15
      freq 2
      pos 744
      pos 786
  term advertisements
    doc 1
      freq 3
      pos 356
      pos 7393
      pos 7739
    doc 12
      freq 1
      pos 4070
  term advertises
    doc 1
      freq 1
      pos 7536
  term advertising
    doc 1
      freq 2
      pos 4234
      pos 7389
  term advic
    doc 12
      freq 2
      pos 6696
      pos 6711
  term advisabl
    doc 1
      freq 1
      pos 8835
    doc 2
      freq 2
      pos 2141
      pos 2192
  term advised
    doc 10
      freq 1
      pos 5965
    doc 17
      freq 2
      pos 1466
      pos 1552
  term advises
    doc 10
      freq 1
      pos 11425
  term af_unspec
    doc 12
      freq 2
      pos 1759
      pos 3314
  term affect
    doc 6
      freq 2
      pos 2778
      pos 2795
    doc 13
      freq 1
      pos 5473
    doc 15
      freq 1
      pos 2379
    doc 17
      freq 1
      pos 1583
  term affected
    doc 1
      freq 1
      pos 5407
    doc 8
      freq 1
      pos 1714
    doc 13
      freq 1
      pos 2081
  term affecting
    doc 6
      freq 1
      pos 2853
    doc 13
      freq 2
      pos 832
      pos 3023
  term affects
    doc 13
      freq 1
      pos 4653
    doc 15
      freq 1
      pos 1410
  term affordabl
    doc 10
      freq 1
      pos 1663
  term afi
    doc 0
      freq 1
      pos 10664
  term aforementioned
    doc 9
      freq 1
      pos 1256
  term after
    doc 0
      freq 4
      pos 2185
      pos 3746
      pos 4272
      pos 5617
    doc 1
      freq 3
      pos 6960
      pos 7394
      pos 7533
    doc 2
      freq 1
      pos 4303
    doc 3
      freq 1
      pos 3367
    doc 4
      freq 1
      pos 1546
    doc 5
      freq 5
      pos 1416
      pos 1630
      pos 2927
      pos 3790
      pos 4006
    doc 6
      freq 4
      pos 1806
      pos 1835
      pos 1858
      pos 1895
    doc 7
      freq 1
      pos 593
    doc 10
      freq 6
      pos 3319
      pos 5405
      pos 8018
      pos 8627
      pos 8923
      pos 9000
    doc 11
      freq 5
      pos 3232
      pos 4099
      pos 4977
      pos 5052
      pos 9229
    doc 12
      freq 4
      pos 1773
      pos 2946
      pos 3094
      pos 5757
    doc 13
      freq 3
      pos 780
      pos 790
      pos 5941
    doc 14
      freq 3
      pos 645
      pos 1970
      pos 1999
    doc 15
      freq 1
      pos 1448
    doc 16
      freq 1
      pos 2502
    doc 17
      freq 1
      pos 1456
    doc 18
      freq 2
      pos 653
      pos 1933
    skipList 
      level 0
        skipDoc 7
        skipDocFP 288559
        impacts 
          impact 
            freq 1
            norm 100
          impact 
            freq 4
            norm 101
          impact 
            freq 5
            norm 104
        impactsEnd 
        skipDoc 17
        skipDocFP 289042
        impacts 
          impact 
            freq 1
            norm 98
          impact 
            freq 3
            norm 107
          impact 
            freq 4
            norm 113
          impact 
            freq 5
            norm 114
          impact 
            freq 6
            norm 116
        impactsEnd 
  term afterwards
    doc 10
      freq 1
      pos 9275
  term again
    doc 1
      freq 1
      pos 1537
    doc 5
      freq 1
      pos 2908
    doc 10
      freq 1
      pos 5342
    doc 12
      freq 1
      pos 9280
  term against
    doc 1
      freq 1
      pos 8720
    doc 4
      freq 6
      pos 4160
      pos 4211
      pos 4238
      pos 4296
      pos 4348
      pos 5444
    doc 5
      freq 2
      pos 1035
      pos 3590
    doc 9
      freq 3
      pos 441
      pos 1128
      pos 1320
    doc 10
      freq 3
      pos 5973
      pos 8455
      pos 9966
    doc 11
      freq 1
      pos 8438
    doc 12
      freq 1
      pos 7376
    doc 13
      freq 2
      pos 5798
      pos 6554
    doc 16
      freq 1
      pos 1371
    skipList 
      level 0
        skipDoc 13
        skipDocFP 290535
        impacts 
          impact 
            freq 3
            norm 95
          impact 
            freq 6
            norm 108
        impactsEnd 
  term agarwal
    doc 11
      freq 1
      pos 9466
  term age
    doc 0
      freq 1
      pos 13297
    doc 13
      freq 1
      pos 4410
  term aged
    doc 0
      freq 1
      pos 7585
  term agent
    doc 0
      freq 41
      pos 2372
      pos 2454
      pos 2515
      pos 2596
      pos 2648
      pos 2698
      pos 2761
      pos 2795
      pos 2843
      pos 2934
      pos 3018
      pos 3161
      pos 3442
      pos 3612
      pos 4128
      pos 4505
      pos 4694
      pos 5347
      pos 5461
      pos 6329
      pos 8877
      pos 9479
      pos 9662
      pos 9888
      pos 10025
      pos 10969
      pos 11759
      pos 12098
      pos 12877
      pos 13131
      pos 13233
      pos 13450
      pos 13548
      pos 13640
      pos 13742
      pos 13815
      pos 13887
      pos 14027
      pos 14156
      pos 14360
      pos 14369
    doc 9
      freq 1
      pos 224
    doc 10
      freq 23
      pos 216
      pos 849
      pos 907
      pos 960
      pos 974
      pos 986
      pos 1358
      pos 1609
      pos 2079
      pos 2125
      pos 2679
      pos 2682
      pos 2700
      pos 3223
      pos 4313
      pos 4332
      pos 4622
      pos 4645
      pos 7809
      pos 8723
      pos 8783
      pos 8972
      pos 10027
    doc 11
      freq 1
      pos 3849
    doc 16
      freq 1
      pos 2046
  term agents
    doc 0
      freq 2
      pos 14394
      pos 14559
    doc 10
      freq 11
      pos 526
      pos 549
      pos 590
      pos 884
      pos 1215
      pos 1689
      pos 4515
      pos 9569
      pos 10864
      pos 12896
      pos 12915
    doc 11
      freq 1
      pos 9051
  term aggarwal
    doc 3
      freq 1
      pos 4667
    doc 8
      freq 1
      pos 1817
  term aggravated
    doc 12
      freq 1
      pos 1729
  term aggregation
    doc 3
      freq 1
      pos 2941
    doc 7
      freq 1
      pos 2469
  term aggressiv
    doc 7
      freq 1
      pos 1504
  term agi
    doc 1
      freq 28
      pos 3258
      pos 3307
      pos 3334
      pos 3354
      pos 3395
      pos 3398
      pos 3412
      pos 3415
      pos 3434
      pos 3489
      pos 3502
      pos 3514
      pos 3531
      pos 3534
      pos 3681
      pos 3685
      pos 3710
      pos 3752
      pos 3826
      pos 3855
      pos 3873
      pos 3892
      pos 3916
      pos 4313
      pos 4408
      pos 4513
      pos 5536
      pos 7212
    doc 8
      freq 10
      pos 151
      pos 1319
      pos 1332
      pos 1340
      pos 1349
      pos 1369
      pos 1389
      pos 1489
      pos 1495
      pos 1502
  term agnostic
    doc 1
      freq 1
      pos 9005
    doc 3
      freq 1
      pos 832
    doc 8
      freq 5
      pos 737
      pos 744
      pos 752
      pos 759
      pos 1895
  term agrawal
    doc 11
      freq 1
      pos 9565
  term agreed
    doc 2
      freq 1
      pos 1335
  term agreement
    doc 2
      freq 1
      pos 4046
    doc 3
      freq 3
      pos 1172
      pos 4051
      pos 5640
    doc 5
      freq 1
      pos 824
  term agrees
    doc 14
      freq 1
      pos 2496
  term ah
    doc 4
      freq 2
      pos 5943
      pos 5950
  term ahawrylyshen
    doc 11
      freq 1
      pos 10552
  term aib
    doc 10
      freq 1
      pos 13178
  term aid
    doc 3
      freq 1
      pos 3549
    doc 4
      freq 2
      pos 3607
      pos 3640
    doc 10
      freq 1
      pos 7746
    doc 14
      freq 1
      pos 417
  term aievziojzwtpaub7iylzklajb5f429truouiedcwmlkblwaqzt6ehwpcnzj7lonc
    doc 10
      freq 1
      pos 6210
  term aii
    doc 1
      freq 12
      pos 3264
      pos 3309
      pos 3336
      pos 3356
      pos 3444
      pos 3468
      pos 3474
      pos 3688
      pos 3695
      pos 3708
      pos 4621
      pos 4629
    doc 8
      freq 7
      pos 1151
      pos 1159
      pos 1168
      pos 1188
      pos 1208
      pos 1294
      pos 1300
  term aii1
    doc 1
      freq 2
      pos 3396
      pos 3416
  term aii2
    doc 1
      freq 2
      pos 3399
      pos 3413
  term aim
    doc 13
      freq 2
      pos 656
      pos 5114
  term aimed
    doc 12
      freq 1
      pos 126
  term aims
    doc 12
      freq 1
      pos 1445
  term air
    doc 2
      freq 1
      pos 2717
  term airtim
    doc 13
      freq 3
      pos 818
      pos 834
      pos 1309
  term ais
    doc 1
      freq 1
      pos 4456
  term aje3br
    doc 11
      freq 1
      pos 5956
  term ak
    doc 15
      freq 1
      pos 3845
  term akay2zocfupkgghfgbyfos8bzx7yl3mzxdzt5zwycj5kezmjewy
    doc 10
      freq 1
      pos 12512
  term aki
    doc 10
      freq 1
      pos 12131
  term akkerhuis
    doc 18
      freq 1
      pos 2026
  term alain
    doc 12
      freq 1
      pos 9428
  term alain_durand
    doc 12
      freq 1
      pos 9439
  term alan
    doc 10
      freq 1
      pos 12121
    doc 11
      freq 3
      pos 10535
      pos 10554
      pos 10562
  term albert
    doc 11
      freq 1
      pos 10545
  term alcatel
    doc 1
      freq 1
      pos 9340
    doc 3
      freq 1
      pos 4843
  term alcatel.com
    doc 1
      freq 1
      pos 9352
    doc 3
      freq 1
      pos 4855
  term alex
    doc 1
      freq 1
      pos 9231
    doc 4
      freq 1
      pos 6044
  term alexander
    doc 11
      freq 2
      pos 6453
      pos 6614
  term alexey
    doc 16
      freq 1
      pos 1592
  term alg
    doc 10
      freq 19
      pos 4836
      pos 4842
      pos 4843
      pos 5432
      pos 5457
      pos 5495
      pos 5732
      pos 6663
      pos 7378
      pos 9420
      pos 9423
      pos 9444
      pos 9469
      pos 9507
      pos 9531
      pos 11955
      pos 12020
      pos 12062
      pos 12078
    doc 12
      freq 3
      pos 418
      pos 6523
      pos 6526
  term algorithm
    doc 0
      freq 4
      pos 5360
      pos 10337
      pos 10357
      pos 10412
    doc 1
      freq 1
      pos 3173
    doc 3
      freq 3
      pos 3768
      pos 3776
      pos 4691
    doc 5
      freq 2
      pos 3198
      pos 3340
    doc 7
      freq 1
      pos 1171
    doc 10
      freq 10
      pos 353
      pos 5427
      pos 5490
      pos 5562
      pos 6164
      pos 9522
      pos 9546
      pos 11959
      pos 12007
      pos 12042
    doc 11
      freq 1
      pos 867
    doc 15
      freq 1
      pos 2034
    doc 18
      freq 3
      pos 1159
      pos 1762
      pos 1783
    skipList 
      level 0
        skipDoc 15
        skipDocFP 297027
        impacts 
          impact 
            freq 1
            norm 100
          impact 
            freq 2
            norm 104
          impact 
            freq 3
            norm 107
          impact 
            freq 10
            norm 116
        impactsEnd 
  term algorithmically
    doc 12
      freq 1
      pos 8179
  term algorithms
    doc 5
      freq 10
      pos 2929
      pos 2986
      pos 3055
      pos 3134
      pos 3171
      pos 3214
      pos 3372
      pos 3396
      pos 3448
      pos 3571
    doc 7
      freq 2
      pos 833
      pos 2243
    doc 10
      freq 1
      pos 13207
    doc 17
      freq 2
      pos 1655
      pos 1667
    doc 18
      freq 2
      pos 1197
      pos 1742
  term algroup.co.uk
    doc 14
      freq 1
      pos 5543
  term aliases
    doc 10
      freq 1
      pos 13041
  term alice
    doc 10
      freq 13
      pos 1798
      pos 1819
      pos 1854
      pos 3048
      pos 6291
      pos 6339
      pos 6414
      pos 6423
      pos 6624
      pos 6927
      pos 6995
      pos 7132
      pos 7345
  term alice's
    doc 10
      freq 3
      pos 1884
      pos 1936
      pos 6445
  term aligned
    doc 0
      freq 1
      pos 10659
  term alike
    doc 11
      freq 1
      pos 7360
  term allan
    doc 3
      freq 1
      pos 4645
    doc 8
      freq 1
      pos 1848
  term alleviat
    doc 7
      freq 1
      pos 1762
  term allison
    doc 5
      freq 1
      pos 4095
  term allocat
    doc 4
      freq 1
      pos 4806
  term allocated
    doc 1
      freq 1
      pos 1762
    doc 2
      freq 1
      pos 6315
    doc 4
      freq 1
      pos 4797
    doc 8
      freq 7
      pos 238
      pos 249
      pos 263
      pos 543
      pos 873
      pos 1199
      pos 1380
    doc 15
      freq 1
      pos 2776
  term allocates
    doc 8
      freq 1
      pos 69
  term allocating
    doc 13
      freq 1
      pos 2398
  term allocation
    doc 2
      freq 7
      pos 152
      pos 1539
      pos 1581
      pos 1603
      pos 1853
      pos 1895
      pos 1913
    doc 4
      freq 2
      pos 5311
      pos 5881
    doc 7
      freq 1
      pos 2455
    doc 8
      freq 9
      pos 97
      pos 204
      pos 383
      pos 420
      pos 427
      pos 928
      pos 1253
      pos 1448
      pos 1561
  term allocations
    doc 1
      freq 4
      pos 2523
      pos 5123
      pos 6087
      pos 8957
    doc 2
      freq 2
      pos 1862
      pos 1925
    doc 3
      freq 1
      pos 4340
    doc 4
      freq 1
      pos 875
    doc 8
      freq 16
      pos 21
      pos 188
      pos 277
      pos 408
      pos 475
      pos 622
      pos 800
      pos 1003
      pos 1127
      pos 1296
      pos 1441
      pos 1491
      pos 1578
      pos 1671
      pos 1932
      pos 2155
  term allonelin
    doc 11
      freq 31
      pos 893
      pos 957
      pos 965
      pos 966
      pos 976
      pos 1907
      pos 1931
      pos 1941
      pos 1964
      pos 1965
      pos 1979
      pos 1993
      pos 1998
      pos 2799
      pos 2838
      pos 2839
      pos 2874
      pos 2887
      pos 2918
      pos 3131
      pos 3147
      pos 3151
      pos 3161
      pos 3776
      pos 3790
      pos 3798
      pos 3809
      pos 3994
      pos 4008
      pos 5025
      pos 5036
  term allow
    doc 0
      freq 4
      pos 2781
      pos 2906
      pos 6106
      pos 16432
    doc 1
      freq 1
      pos 3087
    doc 2
      freq 2
      pos 6101
      pos 6245
    doc 4
      freq 3
      pos 1031
      pos 1686
      pos 2694
    doc 5
      freq 6
      pos 1526
      pos 2535
      pos 2575
      pos 2995
      pos 3378
      pos 3744
    doc 7
      freq 1
      pos 368
    doc 10
      freq 4
      pos 2197
      pos 9814
      pos 10484
      pos 12867
    doc 11
      freq 1
      pos 1887
    doc 12
      freq 1
      pos 6455
    doc 13
      freq 5
      pos 3828
      pos 3991
      pos 4129
      pos 4381
      pos 5504
    doc 15
      freq 2
      pos 365
      pos 2343
    doc 16
      freq 1
      pos 102
    doc 17
      freq 1
      pos 113
    skipList 
      level 0
        skipDoc 11
        skipDocFP 301007
        impacts 
          impact 
            freq 1
            norm 100
          impact 
            freq 6
            norm 104
        impactsEnd 
  term allowed
    doc 0
      freq 1
      pos 16783
    doc 1
      freq 1
      pos 3296
    doc 3
      freq 5
      pos 5076
      pos 5109
      pos 5117
      pos 5129
      pos 5138
    doc 4
      freq 1
      pos 2615
    doc 11
      freq 1
      pos 8018
    doc 12
      freq 3
      pos 4294
      pos 5526
      pos 8794
    doc 13
      freq 2
      pos 3654
      pos 3717
    doc 14
      freq 1
      pos 1894
    skipList 
      level 0
        skipDoc 14
        skipDocFP 302032
        impacts 
          impact 
            freq 5
            norm 107
        impactsEnd 
  term allowing
    doc 2
      freq 1
      pos 1655
    doc 4
      freq 4
      pos 1921
      pos 1964
      pos 5847
      pos 5966
    doc 12
      freq 1
      pos 8335
    doc 17
      freq 1
      pos 1179
  term allows
    doc 0
      freq 1
      pos 16017
    doc 1
      freq 2
      pos 2190
      pos 5377
    doc 2
      freq 2
      pos 4047
      pos 5373
    doc 3
      freq 3
      pos 347
      pos 1270
      pos 1296
    doc 10
      freq 4
      pos 904
      pos 1494
      pos 1605
      pos 5002
    doc 12
      freq 4
      pos 2029
      pos 2049
      pos 2064
      pos 2349
    doc 13
      freq 1
      pos 4092
    doc 16
      freq 1
      pos 187
    skipList 
      level 0
        skipDoc 16
        skipDocFP 302842
        impacts 
          impact 
            freq 1
            norm 99
          impact 
            freq 3
            norm 107
          impact 
            freq 4
            norm 113
        impactsEnd 
  term almeroth
    doc 13
      freq 1
      pos 6925
  term alon
    doc 3
      freq 1
      pos 4921
  term alone
    doc 10
      freq 2
      pos 7567
      pos 8253
  term along
    doc 2
      freq 1
      pos 4198
    doc 5
      freq 1
      pos 3576
    doc 15
      freq 1
      pos 2939
    doc 16
      freq 1
      pos 119
  term alpha
    doc 11
      freq 1
      pos 1613
  term alphanum
    doc 11
      freq 6
      pos 1662
      pos 1707
      pos 1727
      pos 1751
      pos 1764
      pos 1840
  term already
    doc 1
      freq 5
      pos 4727
      pos 6506
      pos 6655
      pos 7756
      pos 7806
    doc 2
      freq 1
      pos 1108
    doc 3
      freq 2
      pos 2087
      pos 2773
    doc 5
      freq 6
      pos 870
      pos 1151
      pos 1704
      pos 2210
      pos 2670
      pos 3901
    doc 8
      freq 1
      pos 300
    doc 9
      freq 1
      pos 378
    doc 10
      freq 5
      pos 1343
      pos 2017
      pos 2257
      pos 2289
      pos 6720
    doc 12
      freq 3
      pos 4843
      pos 5961
      pos 6945
    doc 13
      freq 1
      pos 2687
    doc 14
      freq 1
      pos 632
    doc 16
      freq 4
      pos 126
      pos 140
      pos 209
      pos 335
    skipList 
      level 0
        skipDoc 12
        skipDocFP 304115
        impacts 
          impact 
            freq 1
            norm 95
          impact 
            freq 6
            norm 104
        impactsEnd 
  term also
    doc 0
      freq 4
      pos 371
      pos 5001
      pos 5685
      pos 16448
    doc 1
      freq 11
      pos 141
      pos 806
      pos 1937
      pos 2343
      pos 3033
      pos 4874
      pos 7729
      pos 8109
      pos 8195
      pos 8205
      pos 8426
    doc 2
      freq 11
      pos 1058
      pos 1784
      pos 2042
      pos 2548
      pos 2614
      pos 4206
      pos 4710
      pos 4770
      pos 4941
      pos 5259
      pos 5547
    doc 3
      freq 2
      pos 144
      pos 427
    doc 4
      freq 6
      pos 364
      pos 3682
      pos 3848
      pos 4704
      pos 4988
      pos 5892
    doc 5
      freq 15
      pos 120
      pos 461
      pos 695
      pos 841
      pos 1030
      pos 1040
      pos 1156
      pos 1287
      pos 1678
      pos 1898
      pos 2248
      pos 2492
      pos 2519
      pos 3672
      pos 3917
    doc 6
      freq 7
      pos 112
      pos 758
      pos 1491
      pos 1530
      pos 1626
      pos 2621
      pos 2670
    doc 7
      freq 1
      pos 1283
    doc 8
      freq 12
      pos 100
      pos 609
      pos 615
      pos 933
      pos 987
      pos 993
      pos 1258
      pos 1281
      pos 1287
      pos 1453
      pos 1476
      pos 1482
    doc 9
      freq 3
      pos 316
      pos 534
      pos 898
    doc 10
      freq 20
      pos 1044
      pos 1155
      pos 1747
      pos 1998
      pos 2207
      pos 3333
      pos 4535
      pos 4629
      pos 6116
      pos 6584
      pos 7155
      pos 7183
      pos 7300
      pos 7482
      pos 7911
      pos 8529
      pos 9070
      pos 9211
      pos 9884
      pos 12294
    doc 11
      freq 5
      pos 1716
      pos 6148
      pos 6838
      pos 7078
      pos 9038
    doc 12
      freq 14
      pos 1912
      pos 2218
      pos 2917
      pos 3214
      pos 4173
      pos 4381
      pos 4574
      pos 5152
      pos 5519
      pos 5843
      pos 6235
      pos 6295
      pos 8809
      pos 8874
    doc 13
      freq 17
      pos 464
      pos 514
      pos 550
      pos 633
      pos 884
      pos 1864
      pos 2234
      pos 2472
      pos 3346
      pos 3760
      pos 4506
      pos 5175
      pos 5346
      pos 5638
      pos 6163
      pos 6529
      pos 6541
    doc 15
      freq 12
      pos 483
      pos 851
      pos 940
      pos 1034
      pos 1145
      pos 1476
      pos 2282
      pos 2522
      pos 3057
      pos 3163
      pos 3736
      pos 3881
    doc 16
      freq 9
      pos 286
      pos 383
      pos 422
      pos 475
      pos 1144
      pos 1193
      pos 1390
      pos 1912
      pos 2286
    doc 17
      freq 2
      pos 342
      pos 1501
    skipList 
      level 0
        skipDoc 7
        skipDocFP 305051
        impacts 
          impact 
            freq 1
            norm 100
          impact 
            freq 7
            norm 101
          impact 
            freq 15
            norm 104
        impactsEnd 
        skipDoc 16
        skipDocFP 306082
        impacts 
          impact 
            freq 3
            norm 95
          impact 
            freq 12
            norm 97
          impact 
            freq 17
            norm 109
          impact 
            freq 20
            norm 116
        impactsEnd 
  term alter
    doc 10
      freq 2
      pos 7989
      pos 9856
  term alteration
    doc 1
      freq 2
      pos 8015
      pos 8227
    doc 10
      freq 1
      pos 3401
    doc 13
      freq 1
      pos 5800
  term altered
    doc 1
      freq 1
      pos 8312
    doc 5
      freq 1
      pos 387
  term alternat
    doc 14
      freq 18
      pos 3206
      pos 3525
      pos 3812
      pos 4119
      pos 4182
      pos 4204
      pos 4249
      pos 4270
      pos 4374
      pos 4394
      pos 4464
      pos 4486
      pos 4547
      pos 4568
      pos 4859
      pos 4951
      pos 5122
      pos 5266
    doc 15
      freq 1
      pos 2041
  term alternativ
    doc 1
      freq 1
      pos 5051
    doc 2
      freq 1
      pos 1200
    doc 4
      freq 2
      pos 1231
      pos 2591
    doc 5
      freq 2
      pos 2503
      pos 2529
    doc 9
      freq 1
      pos 156
    doc 12
      freq 1
      pos 4013
    doc 13
      freq 1
      pos 3205
    doc 17
      freq 2
      pos 1787
      pos 1918
    skipList 
      level 0
        skipDoc 17
        skipDocFP 308961
        impacts 
          impact 
            freq 1
            norm 95
          impact 
            freq 2
            norm 98
        impactsEnd 
  term alternatively
    doc 10
      freq 1
      pos 12419
    doc 11
      freq 1
      pos 9826
    doc 12
      freq 1
      pos 6332
    doc 14
      freq 1
      pos 2267
  term alternatives
    doc 0
      freq 1
      pos 11268
    doc 5
      freq 1
      pos 2191
    doc 12
      freq 1
      pos 8858
  term although
    doc 1
      freq 1
      pos 1328
    doc 2
      freq 1
      pos 4826
    doc 10
      freq 2
      pos 5917
      pos 8950
    doc 11
      freq 1
      pos 778
    doc 13
      freq 3
      pos 1926
      pos 2116
      pos 5467
    doc 14
      freq 1
      pos 404
    doc 18
      freq 1
      pos 1755
  term altogether
    doc 11
      freq 1
      pos 6097
    doc 12
      freq 1
      pos 6341
  term alvestrand
    doc 1
      freq 1
      pos 9166
    doc 2
      freq 1
      pos 2358
    doc 5
      freq 1
      pos 4146
    doc 7
      freq 13
      pos 15
      pos 196
      pos 583
      pos 947
      pos 1297
      pos 1645
      pos 1819
      pos 2173
      pos 2531
      pos 2886
      pos 2920
      pos 2933
      pos 3263
    doc 8
      freq 2
      pos 1730
      pos 1747
  term alvestrand.n
    doc 7
      freq 2
      pos 513
      pos 2931
  term always
    doc 1
      freq 3
      pos 1748
      pos 7357
      pos 7613
    doc 5
      freq 1
      pos 3173
    doc 6
      freq 1
      pos 1968
    doc 9
      freq 1
      pos 1190
    doc 10
      freq 3
      pos 3117
      pos 11359
      pos 11440
    doc 11
      freq 2
      pos 5264
      pos 6521
    doc 12
      freq 5
      pos 1115
      pos 1352
      pos 2713
      pos 4536
      pos 8087
    doc 13
      freq 4
      pos 190
      pos 1790
      pos 2574
      pos 3947
    doc 15
      freq 1
      pos 3350
    doc 18
      freq 1
      pos 1847
    skipList 
      level 0
        skipDoc 13
        skipDocFP 310760
        impacts 
          impact 
            freq 1
            norm 95
          impact 
            freq 4
            norm 109
          impact 
            freq 5
            norm 113
        impactsEnd 
  term alwtjyo5e2ggats1ihlz326
    doc 10
      freq 1
      pos 12663
  term am
    doc 10
      freq 1
      pos 7945
  term am6ousxrlhdk7vbgrfnlrvscvsnitu3qkre4bgf3exkmp3dbdus1xm8jgbt
    doc 11
      freq 1
      pos 9917
  term amazinglylongcallernam
    doc 11
      freq 2
      pos 2845
      pos 3157
  term amban
    doc 3
      freq 1
      pos 4801
  term ambiguity
    doc 11
      freq 5
      pos 744
      pos 755
      pos 834
      pos 5448
      pos 6331
  term amend
    doc 14
      freq 1
      pos 391
  term amendment
    doc 2
      freq 1
      pos 2727
  term amendments
    doc 2
      freq 1
      pos 4682
  term americ
    doc 3
      freq 1
      pos 4891
  term american
    doc 1
      freq 1
      pos 9122
  term ammuya1qrggaihvzlvlzq
    doc 10
      freq 1
      pos 6847
  term among
    doc 1
      freq 1
      pos 3227
    doc 12
      freq 1
      pos 7870
    doc 13
      freq 2
      pos 909
      pos 3777
  term amongst
    doc 0
      freq 1
      pos 10092
    doc 10
      freq 1
      pos 5092
  term amount
    doc 1
      freq 1
      pos 710
    doc 4
      freq 2
      pos 1565
      pos 4005
    doc 6
      freq 1
      pos 1304
    doc 10
      freq 1
      pos 9359
    doc 12
      freq 1
      pos 4811
    doc 13
      freq 5
      pos 1890
      pos 2221
      pos 3398
      pos 4345
      pos 4472
  term amsterdam
    doc 13
      freq 1
      pos 7066
  term an
    doc 0
      freq 120
      pos 35
      pos 599
      pos 653
      pos 704
      pos 728
      pos 842
      pos 866
      pos 927
      pos 1333
      pos 1441
      pos 1459
      pos 1834
      pos 2029
      pos 2064
      pos 2131
      pos 2371
      pos 2436
      pos 2453
      pos 2514
      pos 2595
      pos 2647
      pos 2697
      pos 2760
      pos 2794
      pos 2842
      pos 2933
      pos 3017
      pos 3102
      pos 3160
      pos 3194
      pos 3219
      pos 3268
      pos 3441
      pos 3476
      pos 3548
      pos 3611
      pos 3865
      pos 4127
      pos 4365
      pos 4504
      pos 4693
      pos 4920
      pos 5357
      pos 5441
      pos 5460
      pos 5521
      pos 6113
      pos 6307
      pos 6328
      pos 6667
      pos 6888
      pos 6897
      pos 7001
      pos 7038
      pos 7781
      pos 7911
      pos 7996
      pos 8020
      pos 8059
      pos 8065
      pos 8100
      pos 8154
      pos 8160
      pos 8191
      pos 8801
      pos 8864
      pos 8876
      pos 9478
      pos 9507
      pos 9661
      pos 9692
      pos 9887
      pos 10014
      pos 10024
      pos 10213
      pos 10932
      pos 10968
      pos 11229
      pos 11745
      pos 11758
      pos 12084
      pos 12097
      pos 12154
      pos 12369
      pos 12618
      pos 12664
      pos 12681
      pos 12757
      pos 12935
      pos 12959
      pos 13013
      pos 13046
      pos 13101
      pos 13351
      pos 13510
      pos 13610
      pos 13700
      pos 13803
      pos 13809
      pos 13875
      pos 13977
      pos 14212
      pos 14266
      pos 14275
      pos 15469
      pos 15537
      pos 15583
      pos 15663
      pos 16002
      pos 16018
      pos 16055
      pos 16217
      pos 16246
      pos 16259
      pos 16433
      pos 16541
      pos 16837
      pos 17022
      pos 17268
      pos 17444
    doc 1
      freq 53
      pos 52
      pos 122
      pos 161
      pos 458
      pos 550
      pos 706
      pos 852
      pos 878
      pos 930
      pos 1209
      pos 1219
      pos 1246
      pos 1263
      pos 1272
      pos 1282
      pos 1386
      pos 1484
      pos 1509
      pos 1566
      pos 1639
      pos 1830
      pos 2071
      pos 2086
      pos 2092
      pos 2628
      pos 2867
      pos 2871
      pos 3163
      pos 3248
      pos 3254
      pos 3260
      pos 3265
      pos 3915
      pos 4124
      pos 4131
      pos 5032
      pos 5168
      pos 5369
      pos 6342
      pos 7657
      pos 8032
      pos 8095
      pos 8190
      pos 8218
      pos 8470
      pos 8476
      pos 8497
      pos 8532
      pos 8562
      pos 8570
      pos 8747
      pos 9649
      pos 9825
    doc 2
      freq 28
      pos 38
      pos 769
      pos 883
      pos 1086
      pos 1199
      pos 1213
      pos 1262
      pos 1504
      pos 1774
      pos 1867
      pos 1915
      pos 1928
      pos 2023
      pos 2028
      pos 2410
      pos 2852
      pos 3563
      pos 4021
      pos 4129
      pos 4403
      pos 4647
      pos 4779
      pos 5497
      pos 5509
      pos 5895
      pos 6061
      pos 6446
      pos 6622
    doc 3
      freq 46
      pos 46
      pos 100
      pos 115
      pos 343
      pos 374
      pos 512
      pos 813
      pos 934
      pos 1119
      pos 1192
      pos 1284
      pos 1297
      pos 1305
      pos 1328
      pos 1336
      pos 1477
      pos 1660
      pos 1885
      pos 2019
      pos 2261
      pos 2321
      pos 2334
      pos 2483
      pos 2538
      pos 2868
      pos 2872
      pos 2965
      pos 3022
      pos 3098
      pos 3254
      pos 3331
      pos 3389
      pos 3411
      pos 3896
      pos 4093
      pos 4185
      pos 4267
      pos 4329
      pos 4686
      pos 5483
      pos 5492
      pos 5496
      pos 5524
      pos 5545
      pos 5998
      pos 6174
    doc 4
      freq 65
      pos 48
      pos 314
      pos 503
      pos 539
      pos 658
      pos 1041
      pos 1066
      pos 1157
      pos 1230
      pos 1377
      pos 1417
      pos 1480
      pos 1558
      pos 1562
      pos 1596
      pos 1600
      pos 1631
      pos 1648
      pos 1654
      pos 1666
      pos 1706
      pos 1801
      pos 1806
      pos 1816
      pos 1837
      pos 1965
      pos 2014
      pos 2264
      pos 2470
      pos 2524
      pos 2911
      pos 2923
      pos 2940
      pos 2974
      pos 3144
      pos 3167
      pos 3172
      pos 3211
      pos 3371
      pos 3377
      pos 3412
      pos 3472
      pos 3506
      pos 3604
      pos 3665
      pos 3684
      pos 3831
      pos 3850
      pos 3869
      pos 3894
      pos 3903
      pos 3909
      pos 3976
      pos 3980
      pos 4371
      pos 4431
      pos 4456
      pos 4664
      pos 4902
      pos 4981
      pos 5789
      pos 5793
      pos 5843
      pos 6153
      pos 6329
    doc 5
      freq 30
      pos 32
      pos 103
      pos 600
      pos 676
      pos 836
      pos 1166
      pos 1208
      pos 1292
      pos 1333
      pos 2243
      pos 2431
      pos 2454
      pos 2996
      pos 3017
      pos 3095
      pos 3178
      pos 3203
      pos 3243
      pos 3287
      pos 3313
      pos 3384
      pos 3407
      pos 3562
      pos 3624
      pos 3698
      pos 3828
      pos 4150
      pos 4380
      pos 4483
      pos 4659
    doc 6
      freq 14
      pos 41
      pos 226
      pos 870
      pos 935
      pos 992
      pos 1092
      pos 1447
      pos 1942
      pos 1949
      pos 2098
      pos 2633
      pos 2980
      pos 3283
      pos 3459
    doc 7
      freq 18
      pos 27
      pos 52
      pos 76
      pos 317
      pos 569
      pos 579
      pos 678
      pos 712
      pos 894
      pos 1453
      pos 1503
      pos 1756
      pos 2036
      pos 2358
      pos 2450
      pos 2465
      pos 2988
      pos 3164
    doc 8
      freq 6
      pos 36
      pos 390
      pos 1734
      pos 2120
      pos 2205
      pos 2381
    doc 9
      freq 7
      pos 34
      pos 155
      pos 862
      pos 882
      pos 1475
      pos 1850
      pos 2026
    doc 10
      freq 115
      pos 37
      pos 118
      pos 425
      pos 469
      pos 739
      pos 746
      pos 767
      pos 913
      pos 1070
      pos 1121
      pos 1193
      pos 1345
      pos 1419
      pos 1464
      pos 1521
      pos 1547
      pos 1559
      pos 1651
      pos 1780
      pos 1821
      pos 1838
      pos 1843
      pos 2108
      pos 2218
      pos 2241
      pos 2332
      pos 2491
      pos 2504
      pos 2665
      pos 3310
      pos 3335
      pos 3454
      pos 3573
      pos 3613
      pos 3645
      pos 3728
      pos 3757
      pos 3815
      pos 3844
      pos 3856
      pos 3909
      pos 4133
      pos 4433
      pos 4546
      pos 4572
      pos 4631
      pos 4663
      pos 4727
      pos 4752
      pos 5670
      pos 5718
      pos 5731
      pos 6295
      pos 6425
      pos 6449
      pos 6572
      pos 6586
      pos 7029
      pos 7055
      pos 7290
      pos 7302
      pos 7631
      pos 7671
      pos 7691
      pos 7803
      pos 7844
      pos 7871
      pos 8010
      pos 8420
      pos 8501
      pos 8538
      pos 8599
      pos 8622
      pos 8666
      pos 8675
      pos 8730
      pos 8738
      pos 8855
      pos 8955
      pos 8993
      pos 9350
      pos 9365
      pos 9388
      pos 9400
      pos 9403
      pos 9714
      pos 9723
      pos 9751
      pos 9962
      pos 10038
      pos 10097
      pos 10110
      pos 10142
      pos 10283
      pos 10320
      pos 10375
      pos 10523
      pos 10537
      pos 10823
      pos 11012
      pos 11016
      pos 11034
      pos 11083
      pos 11131
      pos 11286
      pos 11385
      pos 11581
      pos 11596
      pos 11874
      pos 12190
      pos 12550
      pos 12967
      pos 12990
      pos 13511
      pos 13687
    doc 11
      freq 76
      pos 54
      pos 170
      pos 675
      pos 766
      pos 857
      pos 1222
      pos 1284
      pos 1621
      pos 1633
      pos 1718
      pos 1775
      pos 1781
      pos 1831
      pos 1886
      pos 2154
      pos 2411
      pos 2427
      pos 2527
      pos 3288
      pos 3476
      pos 4255
      pos 4537
      pos 4545
      pos 4624
      pos 4791
      pos 5008
      pos 5088
      pos 5099
      pos 5111
      pos 5125
      pos 5416
      pos 5428
      pos 5577
      pos 5743
      pos 5863
      pos 5874
      pos 6064
      pos 6083
      pos 6275
      pos 6300
      pos 6312
      pos 6534
      pos 6642
      pos 6805
      pos 6951
      pos 7011
      pos 7055
      pos 7158
      pos 7181
      pos 7285
      pos 7304
      pos 7344
      pos 7420
      pos 7424
      pos 7451
      pos 7631
      pos 7704
      pos 7828
      pos 7900
      pos 7905
      pos 8098
      pos 8106
      pos 8257
      pos 8267
      pos 8275
      pos 8409
      pos 8441
      pos 8582
      pos 8779
      pos 8884
      pos 8981
      pos 9001
      pos 9661
      pos 9742
      pos 10672
      pos 10848
    doc 12
      freq 42
      pos 44
      pos 524
      pos 1402
      pos 1414
      pos 1448
      pos 1510
      pos 1812
      pos 2111
      pos 2411
      pos 2611
      pos 2617
      pos 2637
      pos 3586
      pos 3898
      pos 4176
      pos 4323
      pos 4828
      pos 4868
      pos 4898
      pos 4938
      pos 4978
      pos 5034
      pos 5162
      pos 5616
      pos 5656
      pos 5671
      pos 6029
      pos 6170
      pos 6438
      pos 6590
      pos 6907
      pos 7397
      pos 8366
      pos 8387
      pos 8595
      pos 8988
      pos 9142
      pos 9224
      pos 9291
      pos 9360
      pos 9522
      pos 9698
    doc 13
      freq 62
      pos 53
      pos 590
      pos 820
      pos 866
      pos 1340
      pos 1359
      pos 1371
      pos 1376
      pos 1380
      pos 1403
      pos 1407
      pos 1446
      pos 1472
      pos 1475
      pos 1488
      pos 1492
      pos 1670
      pos 1691
      pos 1759
      pos 1858
      pos 2110
      pos 2457
      pos 2584
      pos 2768
      pos 2865
      pos 2953
      pos 3166
      pos 3240
      pos 3537
      pos 3586
      pos 3698
      pos 3858
      pos 4029
      pos 4218
      pos 4228
      pos 4334
      pos 4512
      pos 4619
      pos 4623
      pos 4797
      pos 4968
      pos 4976
      pos 5047
      pos 5145
      pos 5409
      pos 5603
      pos 5607
      pos 5914
      pos 5933
      pos 5975
      pos 5993
      pos 6273
      pos 6303
      pos 6461
      pos 6472
      pos 6486
      pos 6496
      pos 6500
      pos 6608
      pos 6720
      pos 7137
      pos 7313
    doc 14
      freq 22
      pos 30
      pos 41
      pos 416
      pos 433
      pos 584
      pos 980
      pos 1136
      pos 1361
      pos 1632
      pos 1781
      pos 1964
      pos 1986
      pos 2329
      pos 2641
      pos 2743
      pos 2749
      pos 3226
      pos 3555
      pos 3832
      pos 4523
      pos 5603
      pos 5779
    doc 15
      freq 37
      pos 52
      pos 385
      pos 566
      pos 710
      pos 730
      pos 1063
      pos 1268
      pos 1297
      pos 1362
      pos 1550
      pos 1582
      pos 1607
      pos 1612
      pos 1623
      pos 1722
      pos 1727
      pos 1733
      pos 1926
      pos 1994
      pos 2023
      pos 2033
      pos 2139
      pos 2174
      pos 2189
      pos 2256
      pos 2490
      pos 2536
      pos 2669
      pos 2765
      pos 2948
      pos 3019
      pos 3277
      pos 3345
      pos 3488
      pos 3752
      pos 4122
      pos 4298
    doc 16
      freq 12
      pos 33
      pos 139
      pos 835
      pos 983
      pos 1005
      pos 1039
      pos 1074
      pos 1195
      pos 1557
      pos 1753
      pos 2733
      pos 2909
    doc 17
      freq 36
      pos 30
      pos 118
      pos 123
      pos 229
      pos 299
      pos 314
      pos 352
      pos 388
      pos 394
      pos 408
      pos 415
      pos 418
      pos 445
      pos 601
      pos 613
      pos 947
      pos 1018
      pos 1072
      pos 1115
      pos 1192
      pos 1339
      pos 1368
      pos 1415
      pos 1491
      pos 1495
      pos 1607
      pos 1641
      pos 1673
      pos 1691
      pos 1861
      pos 1932
      pos 1952
      pos 1970
      pos 2079
      pos 2457
      pos 2633
    doc 18
      freq 20
      pos 39
      pos 188
      pos 223
      pos 467
      pos 476
      pos 741
      pos 768
      pos 914
      pos 974
      pos 1042
      pos 1096
      pos 1119
      pos 1263
      pos 1330
      pos 1818
      pos 1843
      pos 1921
      pos 1925
      pos 2245
      pos 2421
    skipList 
      level 0
        skipDoc 7
        skipDocFP 313040
        impacts 
          impact 
            freq 18
            norm 100
          impact 
            freq 30
            norm 104
          impact 
            freq 46
            norm 107
          impact 
            freq 65
            norm 108
          impact 
            freq 120
            norm 120
        impactsEnd 
        skipDoc 15
        skipDocFP 318829
        impacts 
          impact 
            freq 7
            norm 95
          impact 
            freq 37
            norm 104
          impact 
            freq 62
            norm 109
          impact 
            freq 76
            norm 114
          impact 
            freq 115
            norm 116
        impactsEnd 
  term analysis
    doc 2
      freq 4
      pos 2153
      pos 2157
      pos 2855
      pos 5111
    doc 3
      freq 1
      pos 4684
    doc 5
      freq 2
      pos 325
      pos 3560
    doc 10
      freq 1
      pos 9250
    doc 12
      freq 3
      pos 6723
      pos 7592
      pos 8517
    doc 15
      freq 1
      pos 1676
  term analyz
    doc 6
      freq 1
      pos 859
  term analyzed
    doc 12
      freq 1
      pos 3944
  term anavi
    doc 8
      freq 1
      pos 2045
  term and
    doc 0
      freq 127
      pos 44
      pos 47
      pos 69
      pos 293
      pos 360
      pos 409
      pos 438
      pos 578
      pos 968
      pos 1189
      pos 1322
      pos 1451
      pos 1537
      pos 1591
      pos 1674
      pos 1896
      pos 1936
      pos 2433
      pos 2581
      pos 2910
      pos 3267
      pos 3557
      pos 3632
      pos 3651
      pos 3798
      pos 3834
      pos 3864
      pos 3900
      pos 4148
      pos 4167
      pos 4310
      pos 4334
      pos 4364
      pos 4412
      pos 4440
      pos 4450
      pos 4470
      pos 4769
      pos 4906
      pos 5308
      pos 5542
      pos 5669
      pos 5696
      pos 5804
      pos 5843
      pos 5872
      pos 6244
      pos 6679
      pos 6798
      pos 7341
      pos 7743
      pos 7868
      pos 7870
      pos 8261
      pos 8482
      pos 8544
      pos 8601
      pos 9036
      pos 9216
      pos 9275
      pos 10131
      pos 10221
      pos 10348
      pos 10375
      pos 10423
      pos 10674
      pos 10990
      pos 11009
      pos 11174
      pos 11198
      pos 11228
      pos 11424
      pos 11430
      pos 11476
      pos 12007
      pos 12149
      pos 12816
      pos 13025
      pos 13112
      pos 13295
      pos 13304
      pos 13357
      pos 13988
      pos 14013
      pos 14293
      pos 14315
      pos 14429
      pos 14463
      pos 14487
      pos 14523
      pos 14547
      pos 14595
      pos 14629
      pos 14653
      pos 14689
      pos 14713
      pos 14737
      pos 15890
      pos 15908
      pos 15973
      pos 16111
      pos 16165
      pos 16183
      pos 16261
      pos 16591
      pos 16745
      pos 16786
      pos 16816
      pos 16973
      pos 16983
      pos 16999
      pos 17019
      pos 17044
      pos 17065
      pos 17083
      pos 17115
      pos 17136
      pos 17150
      pos 17179
      pos 17183
      pos 17240
      pos 17246
      pos 17260
      pos 17272
      pos 17289
      pos 17419
      pos 17431
    doc 1
      freq 147
      pos 37
      pos 61
      pos 64
      pos 86
      pos 116
      pos 134
      pos 153
      pos 172
      pos 440
      pos 610
      pos 629
      pos 640
      pos 718
      pos 746
      pos 759
      pos 769
      pos 795
      pos 823
      pos 889
      pos 948
      pos 967
      pos 1126
      pos 1145
      pos 1149
      pos 1173
      pos 1250
      pos 1388
      pos 1432
      pos 1599
      pos 1631
      pos 1657
      pos 1667
      pos 1684
      pos 1758
      pos 1812
      pos 1887
      pos 1908
      pos 1950
      pos 1966
      pos 2013
      pos 2042
      pos 2084
      pos 2098
      pos 2181
      pos 2205
      pos 2256
      pos 2445
      pos 2588
      pos 2611
      pos 2752
      pos 2870
      pos 2888
      pos 2916
      pos 3150
      pos 3308
      pos 3325
      pos 3335
      pos 3344
      pos 3355
      pos 3469
      pos 3519
      pos 3540
      pos 3545
      pos 3553
      pos 3578
      pos 3583
      pos 3709
      pos 3751
      pos 3825
      pos 3931
      pos 3977
      pos 3980
      pos 4156
      pos 4202
      pos 4222
      pos 4338
      pos 4410
      pos 4552
      pos 4622
      pos 4771
      pos 4791
      pos 4830
      pos 4885
      pos 4932
      pos 5333
      pos 5483
      pos 5519
      pos 5538
      pos 5559
      pos 5582
      pos 5654
      pos 5903
      pos 5988
      pos 5991
      pos 6112
      pos 6129
      pos 6187
      pos 6222
      pos 6246
      pos 6261
      pos 6331
      pos 6389
      pos 6461
      pos 6561
      pos 6601
      pos 6668
      pos 6729
      pos 6811
      pos 6855
      pos 6916
      pos 7138
      pos 7183
      pos 7214
      pos 7242
      pos 7263
      pos 7404
      pos 7497
      pos 7701
      pos 7910
      pos 7942
      pos 7962
      pos 7984
      pos 8228
      pos 8320
      pos 8395
      pos 8639
      pos 8653
      pos 8659
      pos 8888
      pos 8920
      pos 8942
      pos 8982
      pos 9000
      pos 9031
      pos 9055
      pos 9078
      pos 9091
      pos 9105
      pos 9150
      pos 9173
      pos 9621
      pos 9627
      pos 9641
      pos 9653
      pos 9670
      pos 9800
      pos 9812
    doc 2
      freq 186
      pos 65
      pos 79
      pos 82
      pos 91
      pos 213
      pos 226
      pos 229
      pos 248
      pos 296
      pos 308
      pos 322
      pos 343
      pos 354
      pos 364
      pos 389
      pos 555
      pos 576
      pos 615
      pos 688
      pos 775
      pos 802
      pos 806
      pos 874
      pos 908
      pos 1065
      pos 1114
      pos 1159
      pos 1193
      pos 1248
      pos 1284
      pos 1306
      pos 1380
      pos 1387
      pos 1510
      pos 1531
      pos 1571
      pos 1672
      pos 1697
      pos 1732
      pos 1748
      pos 1787
      pos 1799
      pos 1833
      pos 2027
      pos 2086
      pos 2094
      pos 2116
      pos 2126
      pos 2193
      pos 2230
      pos 2253
      pos 2262
      pos 2307
      pos 2326
      pos 2377
      pos 2395
      pos 2437
      pos 2485
      pos 2506
      pos 2529
      pos 2535
      pos 2561
      pos 2585
      pos 2591
      pos 2610
      pos 2626
      pos 2632
      pos 2646
      pos 2663
      pos 2680
      pos 2711
      pos 2721
      pos 2730
      pos 2738
      pos 2803
      pos 2849
      pos 2885
      pos 2894
      pos 2903
      pos 2924
      pos 2957
      pos 2974
      pos 2994
      pos 3008
      pos 3023
      pos 3051
      pos 3076
      pos 3094
      pos 3108
      pos 3112
      pos 3138
      pos 3167
      pos 3188
      pos 3272
      pos 3288
      pos 3309
      pos 3316
      pos 3334
      pos 3345
      pos 3358
      pos 3372
      pos 3388
      pos 3402
      pos 3429
      pos 3473
      pos 3510
      pos 3542
      pos 3567
      pos 3589
      pos 3605
      pos 3630
      pos 3648
      pos 3668
      pos 3883
      pos 3914
      pos 3922
      pos 3937
      pos 4003
      pos 4014
      pos 4029
      pos 4034
      pos 4049
      pos 4086
      pos 4114
      pos 4178
      pos 4202
      pos 4306
      pos 4333
      pos 4349
      pos 4359
      pos 4368
      pos 4377
      pos 4408
      pos 4433
      pos 4472
      pos 4515
      pos 4557
      pos 4566
      pos 4594
      pos 4674
      pos 4678
      pos 4686
      pos 4754
      pos 4800
      pos 4852
      pos 4868
      pos 4902
      pos 4908
      pos 4912
      pos 4926
      pos 4937
      pos 4946
      pos 4962
      pos 4979
      pos 5016
      pos 5048
      pos 5075
      pos 5098
      pos 5219
      pos 5309
      pos 5321
      pos 5331
      pos 5411
      pos 5432
      pos 5466
      pos 5478
      pos 5499
      pos 5525
      pos 5602
      pos 5624
      pos 5660
      pos 5670
      pos 5716
      pos 5766
      pos 5782
      pos 5897
      pos 6028
      pos 6035
      pos 6232
      pos 6418
      pos 6424
      pos 6438
      pos 6450
      pos 6467
      pos 6597
      pos 6609
    doc 3
      freq 96
      pos 55
      pos 58
      pos 80
      pos 464
      pos 530
      pos 542
      pos 782
      pos 804
      pos 1003
      pos 1021
      pos 1061
      pos 1063
      pos 1070
      pos 1081
      pos 1090
      pos 1098
      pos 1102
      pos 1105
      pos 1147
      pos 1208
      pos 1218
      pos 1248
      pos 1363
      pos 1372
      pos 1407
      pos 1616
      pos 1678
      pos 1832
      pos 1957
      pos 1960
      pos 2081
      pos 2144
      pos 2217
      pos 2272
      pos 2285
      pos 2300
      pos 2337
      pos 2373
      pos 2412
      pos 2459
      pos 3046
      pos 3074
      pos 3133
      pos 3158
      pos 3175
      pos 3231
      pos 3306
      pos 3308
      pos 3326
      pos 3422
      pos 3522
      pos 3560
      pos 3711
      pos 4023
      pos 4055
      pos 4084
      pos 4209
      pos 4260
      pos 4315
      pos 4367
      pos 4372
      pos 4390
      pos 4416
      pos 4422
      pos 4441
      pos 4456
      pos 4485
      pos 4517
      pos 4536
      pos 4573
      pos 4594
      pos 4618
      pos 4630
      pos 4635
      pos 4647
      pos 4665
      pos 4699
      pos 4718
      pos 5043
      pos 5112
      pos 5265
      pos 5476
      pos 5509
      pos 5513
      pos 5624
      pos 5636
      pos 5644
      pos 5841
      pos 5855
      pos 5970
      pos 5976
      pos 5990
      pos 6002
      pos 6019
      pos 6149
      pos 6161
    doc 4
      freq 93
      pos 57
      pos 60
      pos 82
      pos 228
      pos 248
      pos 312
      pos 399
      pos 403
      pos 436
      pos 457
      pos 489
      pos 508
      pos 515
      pos 542
      pos 677
      pos 692
      pos 836
      pos 868
      pos 884
      pos 981
      pos 996
      pos 1001
      pos 1051
      pos 1075
      pos 1281
      pos 1509
      pos 1695
      pos 1828
      pos 2040
      pos 2221
      pos 2419
      pos 2425
      pos 2676
      pos 2841
      pos 3108
      pos 3142
      pos 3409
      pos 3424
      pos 3446
      pos 3485
      pos 3674
      pos 3692
      pos 3840
      pos 3858
      pos 3954
      pos 4015
      pos 4024
      pos 4126
      pos 4243
      pos 4269
      pos 4273
      pos 4288
      pos 4634
      pos 4701
      pos 4728
      pos 4750
      pos 4776
      pos 4807
      pos 4828
      pos 4836
      pos 4853
      pos 4920
      pos 4951
      pos 4960
      pos 5179
      pos 5198
      pos 5230
      pos 5307
      pos 5319
      pos 5332
      pos 5351
      pos 5369
      pos 5425
      pos 5462
      pos 5470
      pos 5502
      pos 5512
      pos 5586
      pos 5702
      pos 5772
      pos 5873
      pos 5889
      pos 5909
      pos 5942
      pos 5949
      pos 6006
      pos 6125
      pos 6131
      pos 6145
      pos 6157
      pos 6174
      pos 6304
      pos 6316
    doc 5
      freq 94
      pos 41
      pos 44
      pos 66
      pos 109
      pos 119
      pos 134
      pos 363
      pos 383
      pos 406
      pos 430
      pos 495
      pos 525
      pos 602
      pos 620
      pos 725
      pos 771
      pos 793
      pos 816
      pos 898
      pos 956
      pos 1001
      pos 1013
      pos 1061
      pos 1178
      pos 1231
      pos 1533
      pos 1910
      pos 1917
      pos 1985
      pos 2016
      pos 2031
      pos 2054
      pos 2081
      pos 2159
      pos 2179
      pos 2299
      pos 2368
      pos 2545
      pos 2600
      pos 2675
      pos 2790
      pos 2797
      pos 2868
      pos 2931
      pos 2960
      pos 2985
      pos 3019
      pos 3054
      pos 3061
      pos 3071
      pos 3133
      pos 3138
      pos 3170
      pos 3215
      pos 3235
      pos 3271
      pos 3368
      pos 3371
      pos 3393
      pos 3447
      pos 3482
      pos 3507
      pos 3509
      pos 3513
      pos 3531
      pos 3540
      pos 3570
      pos 3601
      pos 3640
      pos 3650
      pos 3823
      pos 3898
      pos 3987
      pos 4042
      pos 4073
      pos 4094
      pos 4101
      pos 4144
      pos 4171
      pos 4191
      pos 4213
      pos 4262
      pos 4266
      pos 4276
      pos 4304
      pos 4330
      pos 4362
      pos 4455
      pos 4461
      pos 4475
      pos 4487
      pos 4504
      pos 4634
      pos 4646
    doc 6
      freq 75
      pos 97
      pos 99
      pos 167
      pos 221
      pos 239
      pos 263
      pos 332
      pos 336
      pos 426
      pos 432
      pos 458
      pos 503
      pos 546
      pos 584
      pos 593
      pos 663
      pos 689
      pos 733
      pos 884
      pos 903
      pos 950
      pos 1033
      pos 1068
      pos 1113
      pos 1155
      pos 1186
      pos 1381
      pos 1400
      pos 1427
      pos 1445
      pos 1458
      pos 1514
      pos 1521
      pos 1564
      pos 1666
      pos 1726
      pos 1775
      pos 1892
      pos 1899
      pos 1915
      pos 2160
      pos 2290
      pos 2331
      pos 2358
      pos 2464
      pos 2466
      pos 2557
      pos 2580
      pos 2648
      pos 2700
      pos 2714
      pos 2716
      pos 2719
      pos 2726
      pos 2742
      pos 2844
      pos 2878
      pos 2938
      pos 2971
      pos 3011
      pos 3048
      pos 3069
      pos 3097
      pos 3106
      pos 3159
      pos 3167
      pos 3174
      pos 3250
      pos 3256
      pos 3261
      pos 3275
      pos 3287
      pos 3304
      pos 3434
      pos 3446
    doc 7
      freq 53
      pos 31
      pos 80
      pos 117
      pos 130
      pos 157
      pos 161
      pos 271
      pos 287
      pos 296
      pos 402
      pos 443
      pos 464
      pos 481
      pos 518
      pos 620
      pos 634
      pos 658
      pos 706
      pos 766
      pos 806
      pos 835
      pos 849
      pos 918
      pos 1231
      pos 1340
      pos 1442
      pos 1490
      pos 1523
      pos 1572
      pos 1612
      pos 1635
      pos 1701
      pos 1742
      pos 1750
      pos 1790
      pos 1844
      pos 1980
      pos 2022
      pos 2030
      pos 2156
      pos 2216
      pos 2245
      pos 2259
      pos 2382
      pos 2468
      pos 2765
      pos 2960
      pos 2966
      pos 2980
      pos 2992
      pos 3009
      pos 3139
      pos 3151
    doc 8
      freq 46
      pos 45
      pos 48
      pos 74
      pos 201
      pos 258
      pos 321
      pos 371
      pos 511
      pos 538
      pos 564
      pos 868
      pos 895
      pos 968
      pos 1114
      pos 1194
      pos 1220
      pos 1375
      pos 1401
      pos 1685
      pos 1728
      pos 1754
      pos 1795
      pos 1800
      pos 1815
      pos 1833
      pos 1838
      pos 1850
      pos 1872
      pos 1890
      pos 1907
      pos 1944
      pos 1967
      pos 1992
      pos 2019
      pos 2043
      pos 2067
      pos 2085
      pos 2090
      pos 2106
      pos 2177
      pos 2183
      pos 2197
      pos 2209
      pos 2226
      pos 2356
      pos 2368
    doc 9
      freq 34
      pos 43
      pos 46
      pos 68
      pos 91
      pos 215
      pos 256
      pos 358
      pos 400
      pos 509
      pos 525
      pos 541
      pos 679
      pos 707
      pos 759
      pos 874
      pos 985
      pos 1014
      pos 1104
      pos 1164
      pos 1242
      pos 1417
      pos 1601
      pos 1609
      pos 1654
      pos 1690
      pos 1706
      pos 1746
      pos 1822
      pos 1828
      pos 1842
      pos 1854
      pos 1871
      pos 2001
      pos 2013
    doc 10
      freq 199
      pos 46
      pos 49
      pos 71
      pos 153
      pos 205
      pos 231
      pos 257
      pos 281
      pos 296
      pos 301
      pos 534
      pos 565
      pos 577
      pos 627
      pos 657
      pos 691
      pos 703
      pos 719
      pos 987
      pos 1100
      pos 1234
      pos 1319
      pos 1390
      pos 1508
      pos 1562
      pos 1596
      pos 1618
      pos 1640
      pos 1679
      pos 1729
      pos 1750
      pos 1806
      pos 1823
      pos 1862
      pos 1918
      pos 1938
      pos 1975
      pos 2035
      pos 2058
      pos 2189
      pos 2400
      pos 2481
      pos 2855
      pos 2999
      pos 3054
      pos 3061
      pos 3119
      pos 3308
      pos 3393
      pos 3563
      pos 3651
      pos 3664
      pos 3674
      pos 3752
      pos 3772
      pos 3865
      pos 3957
      pos 4093
      pos 4128
      pos 4253
      pos 4353
      pos 4410
      pos 4564
      pos 4687
      pos 4773
      pos 4979
      pos 5013
      pos 5016
      pos 5064
      pos 5067
      pos 5087
      pos 5126
      pos 5131
      pos 5196
      pos 5274
      pos 5295
      pos 5305
      pos 5370
      pos 5415
      pos 5425
      pos 5502
      pos 5524
      pos 5601
      pos 5611
      pos 5622
      pos 5696
      pos 5870
      pos 5903
      pos 5930
      pos 5942
      pos 6007
      pos 6090
      pos 6172
      pos 6194
      pos 6431
      pos 6767
      pos 6798
      pos 6822
      pos 7035
      pos 7191
      pos 7392
      pos 7544
      pos 7590
      pos 7677
      pos 7743
      pos 7750
      pos 7801
      pos 7966
      pos 8163
      pos 8231
      pos 8260
      pos 8277
      pos 8359
      pos 8415
      pos 8431
      pos 8474
      pos 8480
      pos 8541
      pos 8582
      pos 8654
      pos 8672
      pos 8677
      pos 8692
      pos 8741
      pos 8743
      pos 8759
      pos 8862
      pos 8869
      pos 8914
      pos 8973
      pos 9004
      pos 9029
      pos 9154
      pos 9253
      pos 9270
      pos 9432
      pos 9493
      pos 9514
      pos 9549
      pos 9559
      pos 9774
      pos 9876
      pos 9888
      pos 9911
      pos 10126
      pos 10191
      pos 10241
      pos 10262
      pos 10277
      pos 10292
      pos 10366
      pos 10443
      pos 10475
      pos 10513
      pos 10600
      pos 10712
      pos 10749
      pos 10862
      pos 10877
      pos 10986
      pos 11005
      pos 11169
      pos 11251
      pos 11452
      pos 11463
      pos 11490
      pos 11615
      pos 11710
      pos 11811
      pos 11905
      pos 11980
      pos 12065
      pos 12133
      pos 12169
      pos 12289
      pos 12307
      pos 12435
      pos 13018
      pos 13051
      pos 13105
      pos 13154
      pos 13187
      pos 13218
      pos 13233
      pos 13243
      pos 13256
      pos 13268
      pos 13291
      pos 13340
      pos 13366
      pos 13372
      pos 13389
      pos 13483
      pos 13489
      pos 13503
      pos 13515
      pos 13532
      pos 13662
      pos 13674
    doc 11
      freq 89
      pos 90
      pos 181
      pos 224
      pos 367
      pos 433
      pos 564
      pos 612
      pos 634
      pos 640
      pos 649
      pos 745
      pos 809
      pos 840
      pos 865
      pos 1233
      pos 1240
      pos 1265
      pos 1344
      pos 1730
      pos 1846
      pos 2057
      pos 2188
      pos 2464
      pos 2614
      pos 2639
      pos 2724
      pos 2744
      pos 2749
      pos 2761
      pos 3280
      pos 3558
      pos 3574
      pos 3600
      pos 3711
      pos 3937
      pos 3960
      pos 4192
      pos 4235
      pos 4430
      pos 4576
      pos 4879
      pos 5120
      pos 5727
      pos 5885
      pos 5910
      pos 6117
      pos 6145
      pos 6507
      pos 6545
      pos 6727
      pos 6743
      pos 6812
      pos 7014
      pos 7161
      pos 7354
      pos 7472
      pos 7570
      pos 7675
      pos 7686
      pos 7767
      pos 8095
      pos 8306
      pos 8575
      pos 8672
      pos 8786
      pos 8891
      pos 9159
      pos 9333
      pos 9396
      pos 9454
      pos 9493
      pos 9500
      pos 9514
      pos 9532
      pos 9594
      pos 9607
      pos 9614
      pos 9644
      pos 9658
      pos 9680
      pos 9699
      pos 9842
      pos 10644
      pos 10650
      pos 10664
      pos 10676
      pos 10693
      pos 10823
      pos 10835
    doc 12
      freq 188
      pos 23
      pos 70
      pos 92
      pos 103
      pos 117
      pos 120
      pos 164
      pos 179
      pos 221
      pos 272
      pos 292
      pos 423
      pos 514
      pos 527
      pos 558
      pos 591
      pos 601
      pos 606
      pos 614
      pos 639
      pos 671
      pos 686
      pos 697
      pos 704
      pos 793
      pos 876
      pos 900
      pos 913
      pos 929
      pos 949
      pos 1004
      pos 1078
      pos 1124
      pos 1145
      pos 1188
      pos 1205
      pos 1272
      pos 1369
      pos 1596
      pos 1629
      pos 1660
      pos 1670
      pos 1683
      pos 1690
      pos 1772
      pos 1818
      pos 1871
      pos 1930
      pos 2032
      pos 2061
      pos 2143
      pos 2156
      pos 2169
      pos 2194
      pos 2200
      pos 2243
      pos 2249
      pos 2294
      pos 2379
      pos 2487
      pos 2697
      pos 2716
      pos 2798
      pos 2927
      pos 2942
      pos 3171
      pos 3313
      pos 3466
      pos 3475
      pos 3497
      pos 3515
      pos 3721
      pos 3738
      pos 3865
      pos 3948
      pos 4065
      pos 4146
      pos 4276
      pos 4289
      pos 4359
      pos 4469
      pos 4486
      pos 4518
      pos 4600
      pos 4621
      pos 4684
      pos 4716
      pos 4761
      pos 5054
      pos 5075
      pos 5092
      pos 5135
      pos 5171
      pos 5479
      pos 5561
      pos 5585
      pos 5630
      pos 5688
      pos 5724
      pos 5738
      pos 5903
      pos 5993
      pos 6039
      pos 6175
      pos 6263
      pos 6270
      pos 6312
      pos 6342
      pos 6416
      pos 6481
      pos 6570
      pos 6603
      pos 6665
      pos 6676
      pos 6707
      pos 6717
      pos 6719
      pos 6765
      pos 6770
      pos 6776
      pos 6784
      pos 6795
      pos 6813
      pos 6846
      pos 6877
      pos 6921
      pos 6930
      pos 6938
      pos 6958
      pos 7003
      pos 7018
      pos 7037
      pos 7056
      pos 7060
      pos 7075
      pos 7126
      pos 7144
      pos 7182
      pos 7205
      pos 7266
      pos 7317
      pos 7331
      pos 7356
      pos 7371
      pos 7391
      pos 7411
      pos 7426
      pos 7474
      pos 7493
      pos 7530
      pos 7574
      pos 7583
      pos 7635
      pos 7661
      pos 7680
      pos 7746
      pos 7794
      pos 7863
      pos 7926
      pos 7942
      pos 7974
      pos 8141
      pos 8161
      pos 8215
      pos 8263
      pos 8323
      pos 8331
      pos 8402
      pos 8476
      pos 8483
      pos 8515
      pos 8537
      pos 8686
      pos 8765
      pos 8849
      pos 8863
      pos 8886
      pos 8916
      pos 8999
      pos 9122
      pos 9265
      pos 9494
      pos 9500
      pos 9514
      pos 9526
      pos 9543
      pos 9673
      pos 9685
    doc 13
      freq 189
      pos 81
      pos 85
      pos 96
      pos 106
      pos 113
      pos 140
      pos 204
      pos 232
      pos 280
      pos 312
      pos 366
      pos 389
      pos 404
      pos 417
      pos 451
      pos 512
      pos 546
      pos 559
      pos 574
      pos 586
      pos 649
      pos 663
      pos 691
      pos 864
      pos 874
      pos 906
      pos 927
      pos 932
      pos 965
      pos 971
      pos 1017
      pos 1077
      pos 1099
      pos 1122
      pos 1129
      pos 1158
      pos 1164
      pos 1197
      pos 1230
      pos 1260
      pos 1293
      pos 1317
      pos 1334
      pos 1383
      pos 1416
      pos 1426
      pos 1478
      pos 1572
      pos 1577
      pos 1579
      pos 1593
      pos 1626
      pos 1628
      pos 1636
      pos 1673
      pos 1680
      pos 1687
      pos 1713
      pos 1754
      pos 1778
      pos 1789
      pos 1830
      pos 1883
      pos 1893
      pos 1910
      pos 1921
      pos 1937
      pos 1971
      pos 2073
      pos 2085
      pos 2153
      pos 2216
      pos 2225
      pos 2250
      pos 2292
      pos 2345
      pos 2363
      pos 2376
      pos 2382
      pos 2397
      pos 2409
      pos 2414
      pos 2447
      pos 2520
      pos 2525
      pos 2541
      pos 2590
      pos 2619
      pos 2695
      pos 2763
      pos 2773
      pos 2823
      pos 2870
      pos 2890
      pos 2897
      pos 2906
      pos 2909
      pos 2963
      pos 2984
      pos 2993
      pos 3165
      pos 3223
      pos 3446
      pos 3461
      pos 3472
      pos 3485
      pos 3533
      pos 3572
      pos 3601
      pos 3608
      pos 3642
      pos 3768
      pos 3802
      pos 3902
      pos 3993
      pos 4013
      pos 4085
      pos 4139
      pos 4182
      pos 4235
      pos 4261
      pos 4269
      pos 4319
      pos 4413
      pos 4484
      pos 4496
      pos 4505
      pos 4530
      pos 4565
      pos 4578
      pos 4597
      pos 4600
      pos 4611
      pos 4663
      pos 4702
      pos 4734
      pos 4768
      pos 4888
      pos 4941
      pos 4960
      pos 4971
      pos 4987
      pos 4995
      pos 5037
      pos 5100
      pos 5160
      pos 5248
      pos 5332
      pos 5428
      pos 5513
      pos 5589
      pos 5606
      pos 5622
      pos 5702
      pos 5708
      pos 5711
      pos 5762
      pos 5768
      pos 5787
      pos 5791
      pos 5953
      pos 6023
      pos 6038
      pos 6043
      pos 6318
      pos 6379
      pos 6480
      pos 6601
      pos 6618
      pos 6676
      pos 6702
      pos 6760
      pos 6776
      pos 6815
      pos 6820
      pos 6843
      pos 6864
      pos 6893
      pos 6923
      pos 6930
      pos 6975
      pos 6982
      pos 7109
      pos 7115
      pos 7129
      pos 7141
      pos 7158
      pos 7288
      pos 7300
    doc 14
      freq 89
      pos 21
      pos 48
      pos 80
      pos 220
      pos 313
      pos 315
      pos 347
      pos 402
      pos 420
      pos 459
      pos 472
      pos 480
      pos 563
      pos 663
      pos 679
      pos 801
      pos 834
      pos 847
      pos 961
      pos 1036
      pos 1102
      pos 1164
      pos 1224
      pos 1321
      pos 1340
      pos 1527
      pos 1553
      pos 1688
      pos 1738
      pos 1748
      pos 1874
      pos 1889
      pos 1944
      pos 2037
      pos 2044
      pos 2122
      pos 2153
      pos 2164
      pos 2197
      pos 2209
      pos 2374
      pos 2397
      pos 2480
      pos 2555
      pos 2610
      pos 2618
      pos 2792
      pos 2826
      pos 2873
      pos 2909
      pos 2929
      pos 3262
      pos 3546
      pos 3844
      pos 3860
      pos 4140
      pos 4226
      pos 4291
      pos 4305
      pos 4413
      pos 4427
      pos 4507
      pos 4521
      pos 4589
      pos 4606
      pos 4967
      pos 5038
      pos 5174
      pos 5195
      pos 5326
      pos 5349
      pos 5355
      pos 5368
      pos 5382
      pos 5393
      pos 5410
      pos 5437
      pos 5461
      pos 5471
      pos 5478
      pos 5493
      pos 5554
      pos 5575
      pos 5581
      pos 5595
      pos 5607
      pos 5624
      pos 5754
      pos 5766
    doc 15
      freq 89
      pos 31
      pos 82
      pos 94
      pos 160
      pos 179
      pos 279
      pos 358
      pos 442
      pos 485
      pos 519
      pos 544
      pos 610
      pos 738
      pos 780
      pos 845
      pos 882
      pos 952
      pos 982
      pos 999
      pos 1079
      pos 1111
      pos 1152
      pos 1211
      pos 1214
      pos 1254
      pos 1315
      pos 1533
      pos 1556
      pos 1578
      pos 1637
      pos 1657
      pos 1679
      pos 1712
      pos 1783
      pos 1814
      pos 1835
      pos 1877
      pos 1911
      pos 2103
      pos 2168
      pos 2263
      pos 2267
      pos 2321
      pos 2337
      pos 2390
      pos 2393
      pos 2434
      pos 2450
      pos 2464
      pos 2486
      pos 2517
      pos 2550
      pos 2582
      pos 2689
      pos 2877
      pos 2979
      pos 3021
      pos 3052
      pos 3101
      pos 3146
      pos 3169
      pos 3191
      pos 3238
      pos 3308
      pos 3371
      pos 3396
      pos 3431
      pos 3458
      pos 3462
      pos 3468
      pos 3521
      pos 3614
      pos 3640
      pos 3729
      pos 3772
      pos 3780
      pos 3861
      pos 3912
      pos 3926
      pos 3948
      pos 3981
      pos 4024
      pos 4094
      pos 4100
      pos 4114
      pos 4126
      pos 4143
      pos 4273
      pos 4285
    doc 16
      freq 42
      pos 42
      pos 45
      pos 67
      pos 154
      pos 219
      pos 257
      pos 275
      pos 350
      pos 358
      pos 466
      pos 502
      pos 636
      pos 654
      pos 661
      pos 703
      pos 722
      pos 729
      pos 839
      pos 936
      pos 1036
      pos 1044
      pos 1154
      pos 1159
      pos 1442
      pos 1451
      pos 1462
      pos 1543
      pos 1624
      pos 1633
      pos 1716
      pos 1768
      pos 2483
      pos 2572
      pos 2608
      pos 2624
      pos 2705
      pos 2711
      pos 2725
      pos 2737
      pos 2754
      pos 2884
      pos 2896
    doc 17
      freq 38
      pos 39
      pos 42
      pos 64
      pos 281
      pos 320
      pos 336
      pos 619
      pos 642
      pos 687
      pos 994
      pos 1003
      pos 1105
      pos 1117
      pos 1137
      pos 1172
      pos 1220
      pos 1229
      pos 1384
      pos 1432
      pos 1480
      pos 1577
      pos 1619
      pos 1644
      pos 1654
      pos 1707
      pos 1742
      pos 1771
      pos 2053
      pos 2063
      pos 2076
      pos 2139
      pos 2429
      pos 2435
      pos 2449
      pos 2461
      pos 2478
      pos 2608
      pos 2620
    doc 18
      freq 40
      pos 27
      pos 48
      pos 51
      pos 73
      pos 118
      pos 212
      pos 236
      pos 347
      pos 396
      pos 443
      pos 475
      pos 589
      pos 600
      pos 658
      pos 761
      pos 781
      pos 804
      pos 808
      pos 848
      pos 965
      pos 999
      pos 1236
      pos 1356
      pos 1543
      pos 1617
      pos 1769
      pos 1875
      pos 2031
      pos 2046
      pos 2068
      pos 2074
      pos 2089
      pos 2112
      pos 2217
      pos 2223
      pos 2237
      pos 2249
      pos 2266
      pos 2396
      pos 2408
    skipList 
      level 0
        skipDoc 7
        skipDocFP 326860
        impacts 
          impact 
            freq 53
            norm 100
          impact 
            freq 75
            norm 101
          impact 
            freq 94
            norm 104
          impact 
            freq 96
            norm 107
          impact 
            freq 186
            norm 108
        impactsEnd 
        skipDoc 15
        skipDocFP 340016
        impacts 
          impact 
            freq 34
            norm 95
          impact 
            freq 46
            norm 97
          impact 
            freq 89
            norm 104
          impact 
            freq 189
            norm 109
          impact 
            freq 199
            norm 116
        impactsEnd 
  term andersson
    doc 1
      freq 1
      pos 8912
    doc 2
      freq 1
      pos 6351
    doc 3
      freq 3
      pos 4610
      pos 4697
      pos 4988
  term andrew
    doc 1
      freq 1
      pos 9282
    doc 2
      freq 2
      pos 4276
      pos 4347
    doc 3
      freq 1
      pos 4751
  term andrews
    doc 12
      freq 1
      pos 6786
  term andy.malis
    doc 1
      freq 1
      pos 9295
    doc 3
      freq 1
      pos 4764
  term anfszirmpjnz
    doc 11
      freq 1
      pos 10172
  term angle
    doc 11
      freq 1
      pos 6325
  term anil
    doc 2
      freq 2
      pos 3598
      pos 3629
  term announc
    doc 0
      freq 3
      pos 3937
      pos 3968
      pos 13029
    doc 7
      freq 1
      pos 533
  term announced
    doc 0
      freq 4
      pos 3579
      pos 4059
      pos 4076
      pos 4092
    doc 2
      freq 1
      pos 5437
  term announcement
    doc 2
      freq 2
      pos 1051
      pos 5532
    doc 13
      freq 7
      pos 447
      pos 1163
      pos 1585
      pos 1760
      pos 2114
      pos 3587
      pos 6780
  term announcements
    doc 0
      freq 1
      pos 3561
    doc 13
      freq 2
      pos 1909
      pos 2149
  term anomaly
    doc 6
      freq 1
      pos 1095
  term anonymity
    doc 10
      freq 1
      pos 2955
  term anonymous
    doc 10
      freq 3
      pos 1204
      pos 4475
      pos 7923
  term anonymous.invalid
    doc 10
      freq 2
      pos 7902
      pos 7955
  term anonymously
    doc 13
      freq 1
      pos 6264
  term another
    doc 0
      freq 10
      pos 853
      pos 878
      pos 1363
      pos 6002
      pos 6054
      pos 9966
      pos 10849
      pos 10880
      pos 10913
      pos 11389
    doc 1
      freq 2
      pos 532
      pos 1515
    doc 2
      freq 1
      pos 5795
    doc 4
      freq 1
      pos 1593
    doc 5
      freq 2
      pos 2894
      pos 3036
    doc 6
      freq 1
      pos 2291
    doc 9
      freq 2
      pos 1495
      pos 1542
    doc 10
      freq 2
      pos 2913
      pos 13063
    doc 12
      freq 4
      pos 1578
      pos 2046
      pos 5453
      pos 9235
    doc 13
      freq 1
      pos 1950
    doc 15
      freq 1
      pos 3539
    doc 16
      freq 1
      pos 432
    doc 17
      freq 3
      pos 976
      pos 1786
      pos 1926
    doc 18
      freq 1
      pos 1903
    skipList 
      level 0
        skipDoc 10
        skipDocFP 358085
        impacts 
          impact 
            freq 2
            norm 95
          impact 
            freq 10
            norm 120
        impactsEnd 
  term another's
    doc 3
      freq 1
      pos 2411
  term ansi
    doc 1
      freq 1
      pos 9130
    doc 2
      freq 2
      pos 2549
      pos 2615
    doc 3
      freq 1
      pos 4447
  term answer
    doc 11
      freq 1
      pos 9663
    doc 12
      freq 5
      pos 948
      pos 1008
      pos 1016
      pos 1802
      pos 1882
  term answering
    doc 10
      freq 1
      pos 764
    doc 18
      freq 1
      pos 1036
  term answers
    doc 10
      freq 1
      pos 13019
    doc 12
      freq 1
      pos 1706
  term anti
    doc 4
      freq 1
      pos 5676
  term anticipat
    doc 6
      freq 1
      pos 2495
  term anticipated
    doc 6
      freq 1
      pos 1093
    doc 10
      freq 1
      pos 10921
  term anticipates
    doc 0
      freq 8
      pos 14464
      pos 14488
      pos 14524
      pos 14630
      pos 14654
      pos 14690
      pos 14714
      pos 14738
  term anticipating
    doc 10
      freq 1
      pos 3662
  term anticipation
    doc 10
      freq 1
      pos 2613
  term any
    doc 0
      freq 22
      pos 1467
      pos 2158
      pos 2576
      pos 3568
      pos 3740
      pos 4266
      pos 5294
      pos 5687
      pos 6745
      pos 13706
      pos 16678
      pos 17285
      pos 17306
      pos 17318
      pos 17321
      pos 17345
      pos 17375
      pos 17394
      pos 17399
      pos 17432
      pos 17485
      pos 17493
    doc 1
      freq 23
      pos 904
      pos 934
      pos 1783
      pos 1796
      pos 2621
      pos 3860
      pos 4889
      pos 5327
      pos 6958
      pos 6984
      pos 6994
      pos 7322
      pos 9666
      pos 9687
      pos 9699
      pos 9702
      pos 9726
      pos 9756
      pos 9775
      pos 9780
      pos 9813
      pos 9866
      pos 9874
    doc 2
      freq 14
      pos 42
      pos 4098
      pos 4153
      pos 6463
      pos 6484
      pos 6496
      pos 6499
      pos 6523
      pos 6553
      pos 6572
      pos 6577
      pos 6610
      pos 6663
      pos 6671
    doc 3
      freq 17
      pos 1064
      pos 2143
      pos 2653
      pos 2769
      pos 2888
      pos 2984
      pos 6015
      pos 6036
      pos 6048
      pos 6051
      pos 6075
      pos 6105
      pos 6124
      pos 6129
      pos 6162
      pos 6215
      pos 6223
    doc 4
      freq 19
      pos 865
      pos 923
      pos 1148
      pos 1210
      pos 1547
      pos 2046
      pos 2454
      pos 3593
      pos 6170
      pos 6191
      pos 6203
      pos 6206
      pos 6230
      pos 6260
      pos 6279
      pos 6284
      pos 6317
      pos 6370
      pos 6378
    doc 5
      freq 12
      pos 2597
      pos 4500
      pos 4521
      pos 4533
      pos 4536
      pos 4560
      pos 4590
      pos 4609
      pos 4614
      pos 4647
      pos 4700
      pos 4708
    doc 6
      freq 13
      pos 45
      pos 70
      pos 3300
      pos 3321
      pos 3333
      pos 3336
      pos 3360
      pos 3390
      pos 3409
      pos 3414
      pos 3447
      pos 3500
      pos 3508
    doc 7
      freq 15
      pos 56
      pos 369
      pos 384
      pos 1267
      pos 3005
      pos 3026
      pos 3038
      pos 3041
      pos 3065
      pos 3095
      pos 3114
      pos 3119
      pos 3152
      pos 3205
      pos 3213
    doc 8
      freq 16
      pos 588
      pos 912
      pos 1237
      pos 1418
      pos 1558
      pos 2222
      pos 2243
      pos 2255
      pos 2258
      pos 2282
      pos 2312
      pos 2331
      pos 2336
      pos 2369
      pos 2422
      pos 2430
    doc 9
      freq 12
      pos 1204
      pos 1867
      pos 1888
      pos 1900
      pos 1903
      pos 1927
      pos 1957
      pos 1976
      pos 1981
      pos 2014
      pos 2067
      pos 2075
    doc 10
      freq 31
      pos 972
      pos 2126
      pos 2899
      pos 3148
      pos 3184
      pos 3659
      pos 5282
      pos 7812
      pos 7863
      pos 7893
      pos 8685
      pos 9260
      pos 9337
      pos 9837
      pos 10647
      pos 10910
      pos 11406
      pos 11426
      pos 12440
      pos 12910
      pos 13528
      pos 13549
      pos 13561
      pos 13564
      pos 13588
      pos 13618
      pos 13637
      pos 13642
      pos 13675
      pos 13728
      pos 13736
    doc 11
      freq 30
      pos 58
      pos 569
      pos 660
      pos 753
      pos 850
      pos 911
      pos 927
      pos 1816
      pos 3940
      pos 6748
      pos 6821
      pos 7598
      pos 7690
      pos 7825
      pos 7930
      pos 8704
      pos 8716
      pos 8807
      pos 9847
      pos 10689
      pos 10710
      pos 10722
      pos 10725
      pos 10749
      pos 10779
      pos 10798
      pos 10803
      pos 10836
      pos 10889
      pos 10897
    doc 12
      freq 26
      pos 48
      pos 483
      pos 850
      pos 940
      pos 1040
      pos 1167
      pos 1171
      pos 3358
      pos 3611
      pos 3869
      pos 3890
      pos 4163
      pos 5635
      pos 8065
      pos 8650
      pos 9539
      pos 9560
      pos 9572
      pos 9575
      pos 9599
      pos 9629
      pos 9648
      pos 9653
      pos 9686
      pos 9739
      pos 9747
    doc 13
      freq 25
      pos 57
      pos 855
      pos 1118
      pos 2445
      pos 3344
      pos 3610
      pos 3721
      pos 4650
      pos 4861
      pos 5139
      pos 5152
      pos 5197
      pos 5990
      pos 6396
      pos 7154
      pos 7175
      pos 7187
      pos 7190
      pos 7214
      pos 7244
      pos 7263
      pos 7268
      pos 7301
      pos 7354
      pos 7362
    doc 14
      freq 22
      pos 45
      pos 825
      pos 1027
      pos 1039
      pos 1518
      pos 1679
      pos 1691
      pos 2013
      pos 2024
      pos 2052
      pos 2059
      pos 5620
      pos 5641
      pos 5653
      pos 5656
      pos 5680
      pos 5710
      pos 5729
      pos 5734
      pos 5767
      pos 5820
      pos 5828
    doc 15
      freq 16
      pos 56
      pos 1668
      pos 1708
      pos 2662
      pos 2805
      pos 4139
      pos 4160
      pos 4172
      pos 4175
      pos 4199
      pos 4229
      pos 4248
      pos 4253
      pos 4286
      pos 4339
      pos 4347
    doc 16
      freq 18
      pos 247
      pos 812
      pos 1010
      pos 1122
      pos 1530
      pos 1606
      pos 2499
      pos 2750
      pos 2771
      pos 2783
      pos 2786
      pos 2810
      pos 2840
      pos 2859
      pos 2864
      pos 2897
      pos 2950
      pos 2958
    doc 17
      freq 14
      pos 575
      pos 826
      pos 2334
      pos 2474
      pos 2495
      pos 2507
      pos 2510
      pos 2534
      pos 2564
      pos 2583
      pos 2588
      pos 2621
      pos 2674
      pos 2682
    doc 18
      freq 20
      pos 648
      pos 778
      pos 791
      pos 812
      pos 865
      pos 1274
      pos 1605
      pos 1781
      pos 1979
      pos 2262
      pos 2283
      pos 2295
      pos 2298
      pos 2322
      pos 2352
      pos 2371
      pos 2376
      pos 2409
      pos 2462
      pos 2470
    skipList 
      level 0
        skipDoc 7
        skipDocFP 360156
        impacts 
          impact 
            freq 15
            norm 100
          impact 
            freq 17
            norm 107
          impact 
            freq 19
            norm 108
          impact 
            freq 23
            norm 113
        impactsEnd 
        skipDoc 15
        skipDocFP 362372
        impacts 
          impact 
            freq 12
            norm 95
          impact 
            freq 16
            norm 97
          impact 
            freq 22
            norm 107
          impact 
            freq 25
            norm 109
          impact 
            freq 26
            norm 113
          impact 
            freq 30
            norm 114
          impact 
            freq 31
            norm 116
        impactsEnd 
  term anycast
    doc 4
      freq 4
      pos 1158
      pos 1818
      pos 3913
      pos 5794
  term anyon
    doc 2
      freq 1
      pos 946
    doc 7
      freq 1
      pos 1258
    doc 12
      freq 1
      pos 1454
    doc 18
      freq 2
      pos 357
      pos 484
  term anything
    doc 1
      freq 1
      pos 2992
    doc 7
      freq 1
      pos 1725
    doc 12
      freq 1
      pos 6329
    doc 16
      freq 1
      pos 1015
  term anyway
    doc 11
      freq 2
      pos 4123
      pos 6108
    doc 12
      freq 1
      pos 3687
    doc 13
      freq 1
      pos 5232
    doc 15
      freq 1
      pos 2713
  term anywher
    doc 1
      freq 1
      pos 8459
  term aogbaj7fsfikxkkjwgj8ksgoths3sn19xpscyedbxfem2pj7
    doc 10
      freq 1
      pos 6841
  term aogbak0w3tnefd7ajvqanjnxdtx59aa1vu2jexe6o
    doc 10
      freq 1
      pos 6215
  term aor
    doc 10
      freq 14
      pos 445
      pos 926
      pos 1038
      pos 1088
      pos 1099
      pos 1106
      pos 1885
      pos 2049
      pos 2366
      pos 2958
      pos 4464
      pos 4910
      pos 4958
      pos 10501
    doc 11
      freq 2
      pos 2335
      pos 7632
  term aors
    doc 10
      freq 2
      pos 10574
      pos 13037
  term aoun
    doc 12
      freq 1
      pos 7659
  term aoz
    doc 11
      freq 1
      pos 10036
  term apart
    doc 13
      freq 1
      pos 2800
  term apdtc5b
    doc 10
      freq 1
      pos 6898
  term apdtc5bfsoqxuef
    doc 10
      freq 1
      pos 6902
  term apex
    doc 14
      freq 16
      pos 509
      pos 709
      pos 1085
      pos 1112
      pos 1210
      pos 1405
      pos 1427
      pos 1478
      pos 1582
      pos 1604
      pos 1759
      pos 2896
      pos 3859
      pos 4616
      pos 5037
      pos 5184
  term api
    doc 7
      freq 2
      pos 2808
      pos 2830
  term apis
    doc 12
      freq 2
      pos 6706
      pos 6716
  term apparent
    doc 15
      freq 1
      pos 1259
  term appear
    doc 0
      freq 2
      pos 972
      pos 11814
    doc 1
      freq 1
      pos 1788
    doc 10
      freq 7
      pos 4098
      pos 4781
      pos 5936
      pos 7438
      pos 7489
      pos 8764
      pos 12276
    doc 11
      freq 8
      pos 935
      pos 1824
      pos 2419
      pos 3307
      pos 5901
      pos 7432
      pos 8244
      pos 8698
    doc 15
      freq 1
      pos 1505
    doc 18
      freq 2
      pos 736
      pos 829
  term appeared
    doc 11
      freq 2
      pos 4549
      pos 8279
  term appearing
    doc 11
      freq 2
      pos 906
      pos 929
  term appears
    doc 1
      freq 2
      pos 8260
      pos 8566
    doc 2
      freq 1
      pos 1094
    doc 10
      freq 6
      pos 1990
      pos 6092
      pos 8093
      pos 8178
      pos 11966
      pos 12049
    doc 12
      freq 1
      pos 6681
  term append
    doc 14
      freq 4
      pos 836
      pos 979
      pos 1529
      pos 1631
    doc 16
      freq 33
      pos 99
      pos 220
      pos 231
      pos 294
      pos 419
      pos 542
      pos 598
      pos 601
      pos 604
      pos 629
      pos 692
      pos 800
      pos 817
      pos 828
      pos 974
      pos 1000
      pos 1176
      pos 1223
      pos 1231
      pos 1258
      pos 1299
      pos 1463
      pos 1474
      pos 1774
      pos 1848
      pos 1931
      pos 1935
      pos 2094
      pos 2155
      pos 2243
      pos 2265
      pos 2304
      pos 2464
  term appended
    doc 0
      freq 2
      pos 2403
      pos 10444
    doc 16
      freq 5
      pos 681
      pos 709
      pos 737
      pos 757
      pos 779
  term appendix
    doc 1
      freq 3
      pos 412
      pos 7084
      pos 9408
    doc 2
      freq 7
      pos 165
      pos 180
      pos 333
      pos 3494
      pos 5092
      pos 5292
      pos 6338
    doc 3
      freq 6
      pos 287
      pos 305
      pos 3190
      pos 4033
      pos 5010
      pos 5425
    doc 4
      freq 2
      pos 273
      pos 5538
    doc 7
      freq 2
      pos 499
      pos 1829
    doc 10
      freq 8
      pos 357
      pos 361
      pos 377
      pos 6179
      pos 12100
      pos 12155
      pos 12176
      pos 12837
    doc 11
      freq 4
      pos 542
      pos 767
      pos 855
      pos 9728
    doc 12
      freq 8
      pos 447
      pos 456
      pos 731
      pos 742
      pos 1293
      pos 2892
      pos 7892
      pos 8073
    doc 16
      freq 1
      pos 1694
    doc 17
      freq 4
      pos 466
      pos 2157
      pos 2163
      pos 2205
    skipList 
      level 0
        skipDoc 12
        skipDocFP 370540
        impacts 
          impact 
            freq 2
            norm 100
          impact 
            freq 6
            norm 107
          impact 
            freq 7
            norm 108
          impact 
            freq 8
            norm 113
        impactsEnd 
  term appends
    doc 16
      freq 1
      pos 637
  term appenduid
    doc 16
      freq 3
      pos 1196
      pos 1919
      pos 2091
  term appletalk
    doc 7
      freq 7
      pos 755
      pos 793
      pos 1048
      pos 1195
      pos 2125
      pos 2198
      pos 2625
  term applianc
    doc 1
      freq 2
      pos 28
      pos 9575
  term applicability
    doc 0
      freq 1
      pos 17184
    doc 3
      freq 2
      pos 188
      pos 1264
    doc 6
      freq 1
      pos 92
    doc 7
      freq 4
      pos 266
      pos 747
      pos 2100
      pos 2437
    doc 9
      freq 4
      pos 121
      pos 301
      pos 383
      pos 1102
    doc 10
      freq 2
      pos 3679
      pos 5899
    doc 12
      freq 5
      pos 377
      pos 1432
      pos 4947
      pos 4956
      pos 5249
    doc 13
      freq 3
      pos 487
      pos 1070
      pos 5252
    doc 17
      freq 1
      pos 312
    doc 18
      freq 2
      pos 156
      pos 412
    skipList 
      level 0
        skipDoc 13
        skipDocFP 372146
        impacts 
          impact 
            freq 4
            norm 95
          impact 
            freq 5
            norm 113
        impactsEnd 
  term applicabl
    doc 1
      freq 4
      pos 3968
      pos 5978
      pos 6181
      pos 6248
    doc 3
      freq 2
      pos 1947
      pos 2103
    doc 5
      freq 2
      pos 696
      pos 2828
    doc 6
      freq 3
      pos 82
      pos 579
      pos 589
    doc 9
      freq 1
      pos 618
    doc 10
      freq 2
      pos 10779
      pos 10999
    doc 12
      freq 2
      pos 1642
      pos 2106
    doc 13
      freq 1
      pos 1063
    skipList 
      level 0
        skipDoc 13
        skipDocFP 372985
        impacts 
          impact 
            freq 1
            norm 95
          impact 
            freq 3
            norm 101
          impact 
            freq 4
            norm 113
        impactsEnd 
  term application
    doc 0
      freq 1
      pos 5257
    doc 1
      freq 5
      pos 3343
      pos 3582
      pos 3726
      pos 3734
      pos 3785
    doc 2
      freq 1
      pos 1503
    doc 3
      freq 1
      pos 5634
    doc 4
      freq 2
      pos 3685
      pos 3851
    doc 5
      freq 1
      pos 2841
    doc 6
      freq 4
      pos 872
      pos 1110
      pos 2068
      pos 2239
    doc 9
      freq 2
      pos 627
      pos 649
    doc 10
      freq 6
      pos 749
      pos 5634
      pos 6368
      pos 6668
      pos 10462
      pos 13356
    doc 11
      freq 38
      pos 396
      pos 642
      pos 1499
      pos 2129
      pos 2147
      pos 2231
      pos 3164
      pos 3396
      pos 3534
      pos 3536
      pos 3633
      pos 3737
      pos 3869
      pos 4038
      pos 4307
      pos 4485
      pos 4699
      pos 5190
      pos 5347
      pos 5495
      pos 5655
      pos 5815
      pos 5975
      pos 6199
      pos 6467
      pos 6630
      pos 6890
      pos 7124
      pos 7149
      pos 7162
      pos 7224
      pos 7882
      pos 8173
      pos 8507
      pos 8994
      pos 9059
      pos 9106
      pos 9283
    doc 12
      freq 7
      pos 2375
      pos 3694
      pos 3741
      pos 3746
      pos 6591
      pos 6623
      pos 7359
    doc 13
      freq 16
      pos 1123
      pos 1880
      pos 1924
      pos 2377
      pos 2459
      pos 2803
      pos 3345
      pos 4662
      pos 4942
      pos 5146
      pos 5200
      pos 5270
      pos 5311
      pos 5329
      pos 5341
      pos 5567
    doc 16
      freq 1
      pos 1737
    doc 17
      freq 12
      pos 614
      pos 649
      pos 652
      pos 669
      pos 711
      pos 731
      pos 735
      pos 1078
      pos 1146
      pos 1163
      pos 1232
      pos 1935
    skipList 
      level 0
        skipDoc 9
        skipDocFP 373724
        impacts 
          impact 
            freq 2
            norm 95
          impact 
            freq 4
            norm 101
          impact 
            freq 5
            norm 113
        impactsEnd 
  term applications
    doc 0
      freq 1
      pos 17498
    doc 1
      freq 4
      pos 2958
      pos 3324
      pos 8386
      pos 9879
    doc 2
      freq 6
      pos 85
      pos 232
      pos 1485
      pos 1538
      pos 2148
      pos 6676
    doc 3
      freq 3
      pos 2912
      pos 5147
      pos 6228
    doc 4
      freq 1
      pos 6383
    doc 5
      freq 4
      pos 443
      pos 613
      pos 935
      pos 4713
    doc 6
      freq 9
      pos 204
      pos 340
      pos 355
      pos 732
      pos 856
      pos 1025
      pos 1383
      pos 3079
      pos 3513
    doc 7
      freq 1
      pos 3218
    doc 8
      freq 1
      pos 2435
    doc 9
      freq 2
      pos 1604
      pos 2080
    doc 10
      freq 4
      pos 718
      pos 7400
      pos 10208
      pos 13741
    doc 11
      freq 1
      pos 10902
    doc 12
      freq 9
      pos 424
      pos 4962
      pos 5219
      pos 6571
      pos 6625
      pos 6655
      pos 6689
      pos 6715
      pos 9752
    doc 13
      freq 8
      pos 98
      pos 3680
      pos 3691
      pos 3855
      pos 4701
      pos 5258
      pos 6928
      pos 7367
    doc 14
      freq 1
      pos 5833
    doc 15
      freq 1
      pos 4352
    doc 16
      freq 1
      pos 2963
    doc 17
      freq 2
      pos 324
      pos 2687
    doc 18
      freq 1
      pos 2475
    skipList 
      level 0
        skipDoc 7
        skipDocFP 375800
        impacts 
          impact 
            freq 1
            norm 100
          impact 
            freq 9
            norm 101
        impactsEnd 
        skipDoc 15
        skipDocFP 376409
        impacts 
          impact 
            freq 2
            norm 95
          impact 
            freq 8
            norm 109
          impact 
            freq 9
            norm 113
        impactsEnd 
  term applied
    doc 2
      freq 1
      pos 4572
    doc 5
      freq 3
      pos 173
      pos 1389
      pos 2486
    doc 6
      freq 1
      pos 726
    doc 9
      freq 1
      pos 1223
    doc 10
      freq 4
      pos 735
      pos 3486
      pos 4318
      pos 8017
    doc 12
      freq 1
      pos 4912
  term applies
    doc 0
      freq 3
      pos 2109
      pos 2226
      pos 2252
    doc 1
      freq 2
      pos 7291
      pos 7305
    doc 3
      freq 1
      pos 2402
    doc 4
      freq 1
      pos 408
    doc 5
      freq 1
      pos 2954
    doc 11
      freq 2
      pos 1034
      pos 1120
    doc 17
      freq 3
      pos 378
      pos 1295
      pos 1312
  term apply
    doc 1
      freq 2
      pos 5209
      pos 8427
    doc 4
      freq 2
      pos 1742
      pos 1777
    doc 5
      freq 2
      pos 925
      pos 1554
    doc 10
      freq 1
      pos 1210
    doc 11
      freq 1
      pos 9326
    doc 12
      freq 4
      pos 3150
      pos 3402
      pos 3785
      pos 6010
    doc 13
      freq 1
      pos 6530
    doc 15
      freq 1
      pos 1541
    doc 17
      freq 3
      pos 99
      pos 243
      pos 561
    skipList 
      level 0
        skipDoc 15
        skipDocFP 378313
        impacts 
          impact 
            freq 2
            norm 104
          impact 
            freq 4
            norm 113
        impactsEnd 
  term applying
    doc 2
      freq 1
      pos 1890
    doc 3
      freq 1
      pos 5662
    doc 4
      freq 1
      pos 4167
  term appointed
    doc 2
      freq 3
      pos 460
      pos 4038
      pos 6012
  term approach
    doc 2
      freq 1
      pos 4783
    doc 5
      freq 8
      pos 410
      pos 731
      pos 2208
      pos 2218
      pos 2258
      pos 2445
      pos 2477
      pos 2508
    doc 6
      freq 4
      pos 574
      pos 587
      pos 701
      pos 705
    doc 7
      freq 1
      pos 1505
    doc 10
      freq 1
      pos 643
    doc 12
      freq 1
      pos 5781
    doc 14
      freq 1
      pos 2652
    doc 15
      freq 7
      pos 1583
      pos 1882
      pos 2096
      pos 2476
      pos 2654
      pos 2670
      pos 3611
    doc 18
      freq 2
      pos 1639
      pos 1736
    skipList 
      level 0
        skipDoc 15
        skipDocFP 379231
        impacts 
          impact 
            freq 1
            norm 100
          impact 
            freq 4
            norm 101
          impact 
            freq 8
            norm 104
        impactsEnd 
  term approaches
    doc 5
      freq 1
      pos 227
    doc 6
      freq 1
      pos 752
    doc 10
      freq 2
      pos 10717
      pos 11136
    doc 12
      freq 1
      pos 7449
  term appropriat
    doc 1
      freq 3
      pos 5169
      pos 8191
      pos 8207
    doc 2
      freq 1
      pos 472
    doc 3
      freq 1
      pos 1886
    doc 4
      freq 1
      pos 1514
    doc 6
      freq 1
      pos 2588
    doc 8
      freq 1
      pos 431
    doc 10
      freq 6
      pos 914
      pos 4632
      pos 6010
      pos 6107
      pos 7478
      pos 7521
    doc 11
      freq 5
      pos 4586
      pos 7466
      pos 7496
      pos 8020
      pos 9039
    doc 12
      freq 2
      pos 2735
      pos 4607
    doc 13
      freq 3
      pos 3859
      pos 4409
      pos 4453
    doc 15
      freq 1
      pos 793
    doc 16
      freq 3
      pos 1128
      pos 1148
      pos 1168
    doc 17
      freq 4
      pos 748
      pos 763
      pos 1390
      pos 1481
    doc 18
      freq 2
      pos 1094
      pos 1634
    skipList 
      level 0
        skipDoc 11
        skipDocFP 380314
        impacts 
          impact 
            freq 1
            norm 97
          impact 
            freq 3
            norm 113
          impact 
            freq 5
            norm 114
          impact 
            freq 6
            norm 116
        impactsEnd 
  term appropriately
    doc 5
      freq 1
      pos 2189
    doc 10
      freq 1
      pos 500
  term approv
    doc 8
      freq 1
      pos 447
  term approval
    doc 4
      freq 2
      pos 4856
      pos 5022
  term approved
    doc 2
      freq 4
      pos 5490
      pos 5505
      pos 5562
      pos 6302
    doc 4
      freq 1
      pos 4839
    doc 16
      freq 1
      pos 1652
  term approximately
    doc 7
      freq 1
      pos 550
    doc 18
      freq 1
      pos 322
  term april
    doc 0
      freq 108
      pos 15
      pos 190
      pos 491
      pos 665
      pos 826
      pos 998
      pos 1075
      pos 1207
      pos 1236
      pos 1405
      pos 1617
      pos 1783
      pos 1924
      pos 2100
      pos 2332
      pos 2542
      pos 2723
      pos 2902
      pos 3090
      pos 3251
      pos 3462
      pos 3674
      pos 3809
      pos 4020
      pos 4205
      pos 4408
      pos 4551
      pos 4708
      pos 4824
      pos 5046
      pos 5240
      pos 5477
      pos 5591
      pos 5773
      pos 5954
      pos 6182
      pos 6347
      pos 6437
      pos 6657
      pos 6911
      pos 7090
      pos 7254
      pos 7355
      pos 7517
      pos 7682
      pos 7821
      pos 7955
      pos 8139
      pos 8334
      pos 8424
      pos 8643
      pos 8831
      pos 8931
      pos 9083
      pos 9248
      pos 9442
      pos 9598
      pos 9742
      pos 9908
      pos 10048
      pos 10174
      pos 10388
      pos 10587
      pos 10813
      pos 11025
      pos 11099
      pos 11307
      pos 11488
      pos 11646
      pos 11777
      pos 11883
      pos 12054
      pos 12181
      pos 12317
      pos 12470
      pos 12642
      pos 12790
      pos 12995
      pos 13186
      pos 13345
      pos 13545
      pos 13739
      pos 13929
      pos 14140
      pos 14327
      pos 14504
      pos 14670
      pos 14808
      pos 14928
      pos 15055
      pos 15182
      pos 15312
      pos 15423
      pos 15494
      pos 15565
      pos 15643
      pos 15727
      pos 15804
      pos 16136
      pos 16325
      pos 16477
      pos 16610
      pos 16848
      pos 17058
      pos 17076
      pos 17094
      pos 17106
      pos 17221
    doc 1
      freq 35
      pos 33
      pos 209
      pos 432
      pos 840
      pos 1069
      pos 1377
      pos 1870
      pos 2230
      pos 2426
      pos 2700
      pos 3059
      pos 3429
      pos 3614
      pos 3911
      pos 4248
      pos 4642
      pos 5022
      pos 5301
      pos 5693
      pos 6028
      pos 6369
      pos 6764
      pos 7202
      pos 7644
      pos 7894
      pos 8242
      pos 8710
      pos 8969
      pos 9025
      pos 9119
      pos 9229
      pos 9336
      pos 9406
      pos 9501
      pos 9602
    doc 2
      freq 4
      pos 2246
      pos 2270
      pos 5486
      pos 6007
    doc 3
      freq 26
      pos 28
      pos 174
      pos 339
      pos 586
      pos 766
      pos 1045
      pos 1431
      pos 1784
      pos 2123
      pos 2434
      pos 2829
      pos 3213
      pos 3622
      pos 4016
      pos 4304
      pos 4352
      pos 4382
      pos 4565
      pos 4746
      pos 4839
      pos 4943
      pos 5008
      pos 5204
      pos 5594
      pos 5795
      pos 5951
    doc 4
      freq 1
      pos 5344
    doc 5
      freq 2
      pos 4253
      pos 4313
    doc 6
      freq 10
      pos 17
      pos 295
      pos 748
      pos 1138
      pos 1619
      pos 2034
      pos 2348
      pos 2764
      pos 3041
      pos 3231
    doc 8
      freq 11
      pos 14
      pos 191
      pos 478
      pos 803
      pos 1130
      pos 1444
      pos 1674
      pos 1810
      pos 1935
      pos 2007
      pos 2158
    doc 10
      freq 2
      pos 13251
      pos 13360
    doc 11
      freq 1
      pos 9627
    doc 12
      freq 32
      pos 19
      pos 243
      pos 505
      pos 869
      pos 1227
      pos 1564
      pos 1949
      pos 2283
      pos 2654
      pos 3026
      pos 3390
      pos 3819
      pos 4201
      pos 4566
      pos 5017
      pos 5426
      pos 5862
      pos 6252
      pos 6645
      pos 6990
      pos 7032
      pos 7107
      pos 7237
      pos 7312
      pos 7466
      pos 7710
      pos 7890
      pos 8243
      pos 8640
      pos 9052
      pos 9424
      pos 9475
    doc 13
      freq 2
      pos 6769
      pos 6878
    doc 14
      freq 1
      pos 5485
    doc 15
      freq 1
      pos 3976
    doc 16
      freq 15
      pos 14
      pos 172
      pos 538
      pos 913
      pos 1318
      pos 1573
      pos 1692
      pos 1860
      pos 2118
      pos 2255
      pos 2517
      pos 2567
      pos 2634
      pos 2646
      pos 2686
    doc 17
      freq 2
      pos 2071
      pos 2088
    doc 18
      freq 8
      pos 21
      pos 249
      pos 625
      pos 1033
      pos 1388
      pos 1815
      pos 2155
      pos 2198
    skipList 
      level 0
        skipDoc 8
        skipDocFP 381990
        impacts 
          impact 
            freq 11
            norm 97
          impact 
            freq 26
            norm 107
          impact 
            freq 35
            norm 113
          impact 
            freq 108
            norm 120
        impactsEnd 
        skipDoc 17
        skipDocFP 385157
        impacts 
          impact 
            freq 2
            norm 98
          impact 
            freq 15
            norm 99
          impact 
            freq 32
            norm 113
        impactsEnd 
  term aq2c3czqavgbbb317shcygkk0bag3kwo3m
    doc 10
      freq 1
      pos 6866
  term aqr6wks0mj6ltm
    doc 11
      freq 1
      pos 9969
  term aqzaxxzfhwloks62sqse1p
    doc 11
      freq 1
      pos 9953
  term ar
    doc 16
      freq 1
      pos 1992
  term aravind
    doc 0
      freq 1
      pos 15962
  term arbaugh
    doc 2
      freq 1
      pos 2851
    doc 15
      freq 1
      pos 3928
  term arbitrarily
    doc 1
      freq 1
      pos 8456
    doc 10
      freq 3
      pos 842
      pos 9274
      pos 10156
  term arbitrary
    doc 1
      freq 7
      pos 707
      pos 2629
      pos 4125
      pos 4132
      pos 5475
      pos 6221
      pos 8471
    doc 4
      freq 1
      pos 3658
    doc 10
      freq 2
      pos 9702
      pos 11078
    doc 13
      freq 1
      pos 939
    doc 18
      freq 1
      pos 286
  term arc
    doc 17
      freq 1
      pos 1971
  term arch
    doc 3
      freq 3
      pos 365
      pos 4128
      pos 4385
    doc 4
      freq 2
      pos 4071
      pos 5422
  term architectur
    doc 0
      freq 2
      pos 17009
      pos 17023
    doc 1
      freq 1
      pos 9160
    doc 2
      freq 4
      pos 11
      pos 356
      pos 2232
      pos 3312
    doc 3
      freq 3
      pos 421
      pos 4396
      pos 4527
    doc 4
      freq 5
      pos 4117
      pos 5341
      pos 5373
      pos 5429
      pos 5959
    doc 6
      freq 1
      pos 2979
    doc 7
      freq 7
      pos 895
      pos 1104
      pos 1117
      pos 2359
      pos 2451
      pos 2752
      pos 2776
    doc 10
      freq 2
      pos 1261
      pos 1346
    doc 12
      freq 3
      pos 1259
      pos 7433
      pos 7513
    doc 18
      freq 1
      pos 294
    skipList 
      level 0
        skipDoc 10
        skipDocFP 387968
        impacts 
          impact 
            freq 7
            norm 100
        impactsEnd 
  term architectural
    doc 2
      freq 1
      pos 2340
  term architectures
    doc 10
      freq 2
      pos 1400
      pos 10269
  term archiv
    doc 2
      freq 1
      pos 508
    doc 10
      freq 10
      pos 365
      pos 12152
      pos 12180
      pos 12195
      pos 12298
      pos 12348
      pos 12405
      pos 12408
      pos 12452
      pos 12824
    doc 11
      freq 8
      pos 546
      pos 9732
      pos 9747
      pos 9765
      pos 9810
      pos 9813
      pos 9873
      pos 10509
    doc 16
      freq 1
      pos 391
  term archival
    doc 16
      freq 1
      pos 435
  term archived
    doc 2
      freq 2
      pos 554
      pos 719
  term archives
    doc 2
      freq 3
      pos 127
      pos 729
      pos 907
  term are
    doc 0
      freq 75
      pos 224
      pos 240
      pos 254
      pos 344
      pos 370
      pos 500
      pos 504
      pos 754
      pos 976
      pos 1184
      pos 1676
      pos 2256
      pos 2274
      pos 2871
      pos 3010
      pos 3392
      pos 4075
      pos 4090
      pos 7338
      pos 7342
      pos 7365
      pos 7998
      pos 8468
      pos 8530
      pos 8587
      pos 9022
      pos 9037
      pos 10286
      pos 10318
      pos 10677
      pos 10831
      pos 10841
      pos 11263
      pos 11371
      pos 11381
      pos 12021
      pos 12288
      pos 12903
      pos 12906
      pos 13060
      pos 13157
      pos 13160
      pos 13259
      pos 13262
      pos 13392
      pos 13476
      pos 13479
      pos 13574
      pos 13577
      pos 13666
      pos 13669
      pos 13768
      pos 13771
      pos 13841
      pos 13844
      pos 13913
      pos 13916
      pos 14053
      pos 14056
      pos 14112
      pos 14182
      pos 14185
      pos 14228
      pos 14402
      pos 14424
      pos 14435
      pos 14568
      pos 14590
      pos 14601
      pos 15879
      pos 16092
      pos 16252
      pos 16674
      pos 16690
      pos 17265
    doc 1
      freq 55
      pos 189
      pos 631
      pos 859
      pos 870
      pos 886
      pos 953
      pos 983
      pos 988
      pos 1003
      pos 1178
      pos 1324
      pos 1331
      pos 1936
      pos 2056
      pos 2319
      pos 2342
      pos 2519
      pos 2619
      pos 2874
      pos 2954
      pos 3295
      pos 3315
      pos 3542
      pos 3753
      pos 3849
      pos 3924
      pos 3936
      pos 4773
      pos 4915
      pos 5337
      pos 5355
      pos 5525
      pos 5540
      pos 5588
      pos 5597
      pos 5960
      pos 6083
      pos 6127
      pos 6303
      pos 6782
      pos 7180
      pos 7216
      pos 7269
      pos 7277
      pos 7484
      pos 7608
      pos 7773
      pos 7823
      pos 7937
      pos 8225
      pos 8376
      pos 8416
      pos 8454
      pos 8599
      pos 9646
    doc 2
      freq 28
      pos 330
      pos 402
      pos 459
      pos 525
      pos 536
      pos 553
      pos 705
      pos 718
      pos 1038
      pos 1128
      pos 1162
      pos 1497
      pos 1606
      pos 1794
      pos 1863
      pos 3828
      pos 3909
      pos 3945
      pos 4093
      pos 4144
      pos 4509
      pos 4828
      pos 5360
      pos 5409
      pos 5427
      pos 5445
      pos 6321
      pos 6443
    doc 3
      freq 38
      pos 561
      pos 678
      pos 712
      pos 831
      pos 983
      pos 1015
      pos 1074
      pos 1082
      pos 1253
      pos 1618
      pos 2009
      pos 2146
      pos 2180
      pos 2288
      pos 2494
      pos 2616
      pos 2688
      pos 2772
      pos 2858
      pos 2944
      pos 3051
      pos 3065
      pos 3239
      pos 3251
      pos 3698
      pos 3881
      pos 4030
      pos 4160
      pos 4166
      pos 5115
      pos 5128
      pos 5136
      pos 5388
      pos 5454
      pos 5470
      pos 5519
      pos 5859
      pos 5995
    doc 4
      freq 25
      pos 354
      pos 462
      pos 685
      pos 697
      pos 838
      pos 844
      pos 886
      pos 908
      pos 1671
      pos 1954
      pos 2469
      pos 2678
      pos 3448
      pos 4570
      pos 4628
      pos 4635
      pos 4717
      pos 4781
      pos 4796
      pos 4937
      pos 4974
      pos 4998
      pos 5757
      pos 5932
      pos 6150
    doc 5
      freq 28
      pos 185
      pos 869
      pos 938
      pos 952
      pos 964
      pos 1006
      pos 1066
      pos 1880
      pos 1890
      pos 2026
      pos 2095
      pos 2121
      pos 2192
      pos 2801
      pos 2827
      pos 2854
      pos 2887
      pos 2934
      pos 3056
      pos 3246
      pos 3276
      pos 3707
      pos 3788
      pos 3811
      pos 3900
      pos 4004
      pos 4027
      pos 4480
    doc 6
      freq 17
      pos 76
      pos 80
      pos 394
      pos 428
      pos 476
      pos 696
      pos 757
      pos 1075
      pos 1877
      pos 1881
      pos 1939
      pos 2010
      pos 2064
      pos 2147
      pos 2563
      pos 2584
      pos 3280
    doc 7
      freq 8
      pos 107
      pos 342
      pos 683
      pos 941
      pos 1191
      pos 1324
      pos 1693
      pos 2985
    doc 8
      freq 32
      pos 99
      pos 226
      pos 295
      pos 326
      pos 506
      pos 518
      pos 540
      pos 558
      pos 565
      pos 623
      pos 837
      pos 848
      pos 870
      pos 889
      pos 896
      pos 1004
      pos 1174
      pos 1196
      pos 1214
      pos 1221
      pos 1297
      pos 1355
      pos 1377
      pos 1395
      pos 1402
      pos 1492
      pos 1523
      pos 1534
      pos 1544
      pos 1579
      pos 1712
      pos 2202
    doc 9
      freq 11
      pos 363
      pos 395
      pos 403
      pos 580
      pos 986
      pos 1058
      pos 1227
      pos 1317
      pos 1406
      pos 1623
      pos 1847
    doc 10
      freq 51
      pos 101
      pos 693
      pos 980
      pos 1078
      pos 1124
      pos 1140
      pos 1154
      pos 1267
      pos 1402
      pos 2177
      pos 2300
      pos 2791
      pos 3261
      pos 3362
      pos 3755
      pos 3839
      pos 5107
      pos 5216
      pos 5737
      pos 5964
      pos 6176
      pos 7410
      pos 7973
      pos 8291
      pos 8787
      pos 8966
      pos 9311
      pos 9623
      pos 9808
      pos 9828
      pos 9896
      pos 9930
      pos 9958
      pos 10047
      pos 10294
      pos 10457
      pos 10606
      pos 10731
      pos 10778
      pos 10880
      pos 10998
      pos 11140
      pos 11234
      pos 11290
      pos 11415
      pos 11439
      pos 11502
      pos 12299
      pos 12857
      pos 13020
      pos 13508
    doc 11
      freq 20
      pos 623
      pos 647
      pos 651
      pos 711
      pos 731
      pos 890
      pos 1018
      pos 1820
      pos 2727
      pos 3260
      pos 3757
      pos 4868
      pos 6147
      pos 6516
      pos 6573
      pos 7076
      pos 8364
      pos 9055
      pos 9364
      pos 10669
    doc 12
      freq 64
      pos 593
      pos 622
      pos 760
      pos 771
      pos 1103
      pos 1237
      pos 1245
      pos 1249
      pos 1286
      pos 1349
      pos 1434
      pos 1548
      pos 1637
      pos 1654
      pos 1674
      pos 1720
      pos 1728
      pos 1736
      pos 1746
      pos 1855
      pos 1931
      pos 1960
      pos 1970
      pos 2019
      pos 2083
      pos 2099
      pos 2403
      pos 2541
      pos 2666
      pos 2689
      pos 2695
      pos 2711
      pos 2810
      pos 3039
      pos 3120
      pos 3232
      pos 3462
      pos 3471
      pos 3857
      pos 4117
      pos 4253
      pos 4398
      pos 4467
      pos 4504
      pos 4793
      pos 5277
      pos 5467
      pos 5477
      pos 5604
      pos 5728
      pos 5882
      pos 6190
      pos 6216
      pos 6316
      pos 6874
      pos 7985
      pos 8120
      pos 8208
      pos 8251
      pos 8621
      pos 8808
      pos 8859
      pos 9402
      pos 9519
    doc 13
      freq 29
      pos 101
      pos 495
      pos 566
      pos 1061
      pos 1091
      pos 1115
      pos 1202
      pos 1537
      pos 1638
      pos 2060
      pos 2080
      pos 2190
      pos 2452
      pos 2764
      pos 2791
      pos 2845
      pos 3239
      pos 3506
      pos 3529
      pos 3806
      pos 4111
      pos 4613
      pos 4742
      pos 5501
      pos 5625
      pos 5656
      pos 6312
      pos 6470
      pos 7134
    doc 14
      freq 15
      pos 52
      pos 412
      pos 475
      pos 574
      pos 669
      pos 1053
      pos 1168
      pos 1705
      pos 1893
      pos 1921
      pos 2078
      pos 2175
      pos 2564
      pos 2934
      pos 5600
    doc 15
      freq 26
      pos 496
      pos 683
      pos 787
      pos 880
      pos 1010
      pos 1226
      pos 1493
      pos 1528
      pos 1715
      pos 1893
      pos 1946
      pos 2031
      pos 2077
      pos 2231
      pos 2240
      pos 2501
      pos 2524
      pos 2646
      pos 2731
      pos 2957
      pos 3056
      pos 3228
      pos 3357
      pos 3513
      pos 3812
      pos 4119
    doc 16
      freq 14
      pos 302
      pos 410
      pos 680
      pos 756
      pos 778
      pos 898
      pos 1207
      pos 1271
      pos 1455
      pos 1610
      pos 1627
      pos 1643
      pos 1704
      pos 2730
    doc 17
      freq 16
      pos 256
      pos 286
      pos 384
      pos 470
      pos 587
      pos 999
      pos 1042
      pos 1223
      pos 1280
      pos 1301
      pos 1318
      pos 1465
      pos 1551
      pos 1676
      pos 1872
      pos 2454
    doc 18
      freq 8
      pos 401
      pos 717
      pos 894
      pos 1558
      pos 1717
      pos 1744
      pos 1867
      pos 2242
    skipList 
      level 0
        skipDoc 7
        skipDocFP 389563
        impacts 
          impact 
            freq 8
            norm 100
          impact 
            freq 17
            norm 101
          impact 
            freq 28
            norm 104
          impact 
            freq 38
            norm 107
          impact 
            freq 55
            norm 113
          impact 
            freq 75
            norm 120
        impactsEnd 
        skipDoc 15
        skipDocFP 393856
        impacts 
          impact 
            freq 11
            norm 95
          impact 
            freq 32
            norm 97
          impact 
            freq 64
            norm 113
        impactsEnd 
  term area
    doc 0
      freq 33
      pos 497
      pos 520
      pos 600
      pos 767
      pos 1290
      pos 1309
      pos 1903
      pos 2408
      pos 3028
      pos 3049
      pos 3148
      pos 3188
      pos 3317
      pos 3323
      pos 3334
      pos 3368
      pos 3420
      pos 3477
      pos 4449
      pos 4686
      pos 7491
      pos 8108
      pos 9370
      pos 9376
      pos 9383
      pos 9414
      pos 9460
      pos 9540
      pos 12450
      pos 12758
      pos 12858
      pos 13210
      pos 13707
    doc 2
      freq 14
      pos 411
      pos 414
      pos 1286
      pos 1674
      pos 2487
      pos 2508
      pos 2537
      pos 2563
      pos 2571
      pos 2593
      pos 2634
      pos 2713
      pos 3431
      pos 5883
    doc 3
      freq 3
      pos 4424
      pos 4458
      pos 4463
    doc 4
      freq 1
      pos 4854
    doc 7
      freq 3
      pos 294
      pos 871
      pos 2281
    doc 12
      freq 1
      pos 4370
    doc 13
      freq 4
      pos 1083
      pos 1799
      pos 1810
      pos 2639
    doc 15
      freq 1
      pos 3743
    skipList 
      level 0
        skipDoc 15
        skipDocFP 399104
        impacts 
          impact 
            freq 3
            norm 100
          impact 
            freq 14
            norm 108
          impact 
            freq 33
            norm 120
        impactsEnd 
  term areaaddresses
    doc 0
      freq 2
      pos 3400
      pos 12843
  term areaaddressesofneighbour
    doc 0
      freq 1
      pos 9428
  term areas
    doc 0
      freq 1
      pos 9511
    doc 1
      freq 1
      pos 8003
    doc 2
      freq 2
      pos 405
      pos 1726
    doc 6
      freq 2
      pos 107
      pos 2306
    doc 11
      freq 1
      pos 697
    doc 13
      freq 1
      pos 2804
    doc 15
      freq 2
      pos 281
      pos 3054
  term aren't
    doc 10
      freq 1
      pos 9906
    doc 12
      freq 1
      pos 5525
    doc 15
      freq 1
      pos 2085
  term arends
    doc 14
      freq 2
      pos 5429
      pos 5489
    doc 18
      freq 3
      pos 2060
      pos 2081
      pos 2104
  term arguably
    doc 7
      freq 1
      pos 1357
    doc 12
      freq 1
      pos 6417
  term argue
    doc 15
      freq 1
      pos 3014
  term argued
    doc 12
      freq 2
      pos 2965
      pos 8922
    doc 15
      freq 1
      pos 3336
  term argues
    doc 10
      freq 1
      pos 9983
  term argument
    doc 12
      freq 1
      pos 3013
    doc 15
      freq 2
      pos 2257
      pos 2364
  term arguments
    doc 16
      freq 3
      pos 246
      pos 544
      pos 626
  term arise
    doc 9
      freq 1
      pos 1405
    doc 10
      freq 1
      pos 2951
  term arisen
    doc 2
      freq 1
      pos 767
  term arises
    doc 13
      freq 1
      pos 2867
  term arithmetic
    doc 7
      freq 1
      pos 2850
  term arkko
    doc 2
      freq 1
      pos 2799
    doc 5
      freq 1
      pos 4163
    doc 9
      freq 3
      pos 1637
      pos 1656
      pos 1740
  term arose
    doc 2
      freq 1
      pos 5739
  term around
    doc 7
      freq 1
      pos 537
  term arp
    doc 2
      freq 1
      pos 6123
  term arpa
    doc 12
      freq 3
      pos 783
      pos 5350
      pos 7164
  term arrangement
    doc 2
      freq 3
      pos 4917
      pos 5674
      pos 6226
  term arrangements
    doc 2
      freq 2
      pos 1205
      pos 5450
  term array
    doc 11
      freq 1
      pos 4644
  term arriv
    doc 1
      freq 1
      pos 7559
    doc 6
      freq 1
      pos 1955
    doc 11
      freq 1
      pos 4590
  term arrival
    doc 4
      freq 1
      pos 2556
    doc 6
      freq 9
      pos 219
      pos 1182
      pos 1538
      pos 1793
      pos 1808
      pos 1839
      pos 1860
      pos 1961
      pos 2008
    doc 15
      freq 1
      pos 346
  term arrived
    doc 0
      freq 1
      pos 14284
    doc 1
      freq 1
      pos 522
    doc 11
      freq 2
      pos 3220
      pos 4391
  term arrives
    doc 1
      freq 2
      pos 497
      pos 1397
    doc 3
      freq 1
      pos 2278
    doc 6
      freq 3
      pos 1714
      pos 1771
      pos 1979
    doc 10
      freq 1
      pos 10140
    doc 11
      freq 2
      pos 4567
      pos 8297
  term artifacts
    doc 6
      freq 1
      pos 2657
  term as
    doc 0
      freq 46
      pos 319
      pos 336
      pos 675
      pos 701
      pos 773
      pos 791
      pos 810
      pos 980
      pos 1135
      pos 1151
      pos 1244
      pos 2210
      pos 2882
      pos 2884
      pos 2916
      pos 3215
      pos 4077
      pos 4924
      pos 5290
      pos 5548
      pos 5983
      pos 6035
      pos 6227
      pos 6532
      pos 6581
      pos 6807
      pos 6870
      pos 7989
      pos 9389
      pos 9420
      pos 9542
      pos 9575
      pos 9619
      pos 9727
      pos 9765
      pos 9812
      pos 9844
      pos 9875
      pos 9927
      pos 11984
      pos 15885
      pos 16418
      pos 16725
      pos 16775
      pos 17248
      pos 17269
    doc 1
      freq 68
      pos 110
      pos 740
      pos 821
      pos 912
      pos 914
      pos 1122
      pos 1128
      pos 1182
      pos 1458
      pos 1523
      pos 1822
      pos 2247
      pos 2448
      pos 2549
      pos 2657
      pos 2779
      pos 2785
      pos 2828
      pos 2944
      pos 3064
      pos 3074
      pos 3133
      pos 3213
      pos 3273
      pos 3358
      pos 3393
      pos 3634
      pos 3756
      pos 3872
      pos 4152
      pos 4426
      pos 4487
      pos 4498
      pos 4574
      pos 4692
      pos 4823
      pos 4825
      pos 4877
      pos 5117
      pos 5190
      pos 5353
      pos 5440
      pos 5494
      pos 5631
      pos 6014
      pos 6101
      pos 6481
      pos 6525
      pos 6627
      pos 6783
      pos 6796
      pos 6936
      pos 6982
      pos 7095
      pos 7150
      pos 8119
      pos 8121
      pos 8129
      pos 8132
      pos 8511
      pos 8518
      pos 8628
      pos 8688
      pos 8814
      pos 8867
      pos 9462
      pos 9629
      pos 9650
    doc 2
      freq 93
      pos 104
      pos 106
      pos 461
      pos 471
      pos 480
      pos 482
      pos 501
      pos 503
      pos 768
      pos 993
      pos 995
      pos 1045
      pos 1196
      pos 1251
      pos 1357
      pos 1520
      pos 1557
      pos 1752
      pos 1806
      pos 1868
      pos 1884
      pos 1943
      pos 2134
      pos 2155
      pos 2181
      pos 2203
      pos 3562
      pos 3572
      pos 3693
      pos 3759
      pos 3943
      pos 3995
      pos 4111
      pos 4182
      pos 4371
      pos 4394
      pos 4414
      pos 4424
      pos 4483
      pos 4488
      pos 4521
      pos 4614
      pos 4628
      pos 4646
      pos 4649
      pos 4750
      pos 4778
      pos 4818
      pos 4885
      pos 4887
      pos 4889
      pos 4934
      pos 4974
      pos 5003
      pos 5005
      pos 5049
      pos 5100
      pos 5178
      pos 5180
      pos 5204
      pos 5206
      pos 5244
      pos 5246
      pos 5378
      pos 5444
      pos 5496
      pos 5508
      pos 5565
      pos 5586
      pos 5655
      pos 5681
      pos 5683
      pos 5785
      pos 5846
      pos 5956
      pos 5977
      pos 5979
      pos 6056
      pos 6077
      pos 6079
      pos 6099
      pos 6146
      pos 6148
      pos 6162
      pos 6164
      pos 6180
      pos 6204
      pos 6236
      pos 6243
      pos 6275
      pos 6309
      pos 6426
      pos 6447
    doc 3
      freq 29
      pos 400
      pos 403
      pos 471
      pos 691
      pos 778
      pos 784
      pos 1110
      pos 1257
      pos 2011
      pos 2152
      pos 2562
      pos 2622
      pos 3038
      pos 3280
      pos 3603
      pos 3629
      pos 3870
      pos 3933
      pos 4106
      pos 4108
      pos 4124
      pos 4164
      pos 4216
      pos 5060
      pos 5156
      pos 5329
      pos 5620
      pos 5978
      pos 5999
    doc 4
      freq 42
      pos 295
      pos 371
      pos 412
      pos 466
      pos 497
      pos 699
      pos 876
      pos 954
      pos 1105
      pos 1152
      pos 1291
      pos 1440
      pos 1454
      pos 1639
      pos 1732
      pos 1767
      pos 1933
      pos 1935
      pos 2132
      pos 2137
      pos 2798
      pos 2803
      pos 2895
      pos 2918
      pos 3043
      pos 3048
      pos 3187
      pos 3279
      pos 3284
      pos 3885
      pos 4311
      pos 4313
      pos 4436
      pos 4540
      pos 4566
      pos 4709
      pos 4873
      pos 4910
      pos 4992
      pos 5802
      pos 6133
      pos 6154
    doc 5
      freq 32
      pos 417
      pos 440
      pos 584
      pos 586
      pos 665
      pos 667
      pos 993
      pos 1070
      pos 1200
      pos 1346
      pos 1428
      pos 1486
      pos 1700
      pos 1792
      pos 2132
      pos 2134
      pos 2277
      pos 2302
      pos 2308
      pos 2373
      pos 2384
      pos 2481
      pos 2781
      pos 2832
      pos 2961
      pos 3104
      pos 3497
      pos 3535
      pos 3724
      pos 3843
      pos 4463
      pos 4484
    doc 6
      freq 40
      pos 90
      pos 108
      pos 130
      pos 189
      pos 206
      pos 258
      pos 342
      pos 357
      pos 380
      pos 382
      pos 446
      pos 556
      pos 620
      pos 628
      pos 630
      pos 645
      pos 761
      pos 888
      pos 932
      pos 934
      pos 999
      pos 1057
      pos 1299
      pos 1494
      pos 1591
      pos 1731
      pos 1851
      pos 1917
      pos 1924
      pos 2134
      pos 2262
      pos 2502
      pos 2554
      pos 2613
      pos 2639
      pos 2661
      pos 2704
      pos 2830
      pos 3263
      pos 3284
    doc 7
      freq 18
      pos 84
      pos 103
      pos 110
      pos 255
      pos 333
      pos 388
      pos 432
      pos 446
      pos 1174
      pos 1194
      pos 1208
      pos 1220
      pos 1384
      pos 1428
      pos 1561
      pos 1598
      pos 2968
      pos 2989
    doc 8
      freq 10
      pos 330
      pos 342
      pos 943
      pos 1102
      pos 1261
      pos 1456
      pos 1504
      pos 1580
      pos 2185
      pos 2206
    doc 9
      freq 17
      pos 199
      pos 201
      pos 260
      pos 332
      pos 367
      pos 377
      pos 445
      pos 714
      pos 762
      pos 788
      pos 989
      pos 1004
      pos 1081
      pos 1197
      pos 1583
      pos 1830
      pos 1851
    doc 10
      freq 69
      pos 435
      pos 452
      pos 543
      pos 607
      pos 697
      pos 893
      pos 1192
      pos 1650
      pos 1954
      pos 2222
      pos 2230
      pos 2240
      pos 2303
      pos 2309
      pos 2372
      pos 2620
      pos 2760
      pos 2882
      pos 2917
      pos 3008
      pos 3059
      pos 3399
      pos 3548
      pos 3620
      pos 3683
      pos 3841
      pos 3912
      pos 4477
      pos 4614
      pos 4726
      pos 4929
      pos 5072
      pos 5214
      pos 5507
      pos 5518
      pos 5529
      pos 5882
      pos 5921
      pos 6420
      pos 7024
      pos 7102
      pos 7413
      pos 7797
      pos 7802
      pos 7859
      pos 7913
      pos 7967
      pos 8294
      pos 8483
      pos 8589
      pos 9035
      pos 9561
      pos 9584
      pos 9602
      pos 9918
      pos 10082
      pos 10096
      pos 10282
      pos 10494
      pos 10522
      pos 11160
      pos 11314
      pos 12273
      pos 12359
      pos 12437
      pos 13062
      pos 13066
      pos 13491
      pos 13512
    doc 11
      freq 59
      pos 589
      pos 604
      pos 1021
      pos 1115
      pos 1133
      pos 1150
      pos 1179
      pos 1354
      pos 1382
      pos 1415
      pos 1641
      pos 2123
      pos 2139
      pos 2153
      pos 2340
      pos 2478
      pos 2507
      pos 2650
      pos 2668
      pos 3484
      pos 3585
      pos 3596
      pos 3731
      pos 4115
      pos 4372
      pos 4398
      pos 4602
      pos 4640
      pos 4825
      pos 4844
      pos 5575
      pos 5741
      pos 5851
      pos 6040
      pos 6061
      pos 6132
      pos 6567
      pos 7070
      pos 7298
      pos 7444
      pos 7458
      pos 7470
      pos 7595
      pos 7630
      pos 7822
      pos 7927
      pos 7970
      pos 8007
      pos 8440
      pos 8588
      pos 8668
      pos 8687
      pos 8699
      pos 8796
      pos 9336
      pos 9776
      pos 9844
      pos 10652
      pos 10673
    doc 12
      freq 85
      pos 897
      pos 1045
      pos 1340
      pos 1392
      pos 1506
      pos 1538
      pos 1876
      pos 1878
      pos 1982
      pos 1984
      pos 2464
      pos 2590
      pos 2678
      pos 3166
      pos 3243
      pos 3245
      pos 3500
      pos 3574
      pos 3675
      pos 3725
      pos 3853
      pos 4041
      pos 4101
      pos 4110
      pos 4112
      pos 4141
      pos 4334
      pos 4520
      pos 4916
      pos 4987
      pos 5100
      pos 5112
      pos 5169
      pos 5223
      pos 5239
      pos 5241
      pos 5313
      pos 5396
      pos 5398
      pos 5454
      pos 5511
      pos 5562
      pos 5567
      pos 5577
      pos 5803
      pos 5897
      pos 5924
      pos 5984
      pos 6007
      pos 6110
      pos 6134
      pos 6205
      pos 6280
      pos 6308
      pos 6322
      pos 6347
      pos 6363
      pos 6388
      pos 6406
      pos 6435
      pos 6463
      pos 6601
      pos 6610
      pos 6612
      pos 8166
      pos 8224
      pos 8339
      pos 8382
      pos 8446
      pos 8672
      pos 8691
      pos 8699
      pos 8706
      pos 8724
      pos 8768
      pos 8777
      pos 8779
      pos 8797
      pos 8801
      pos 9034
      pos 9061
      pos 9092
      pos 9130
      pos 9502
      pos 9523
    doc 13
      freq 49
      pos 381
      pos 383
      pos 410
      pos 412
      pos 430
      pos 434
      pos 456
      pos 553
      pos 569
      pos 578
      pos 803
      pos 823
      pos 847
      pos 849
      pos 1125
      pos 1206
      pos 1524
      pos 1781
      pos 1934
      pos 2462
      pos 2530
      pos 2594
      pos 2666
      pos 2806
      pos 2827
      pos 2860
      pos 2903
      pos 3067
      pos 3106
      pos 3479
      pos 3552
      pos 3560
      pos 3615
      pos 3989
      pos 4648
      pos 4715
      pos 4718
      pos 4957
      pos 5326
      pos 5698
      pos 5700
      pos 5745
      pos 5747
      pos 6127
      pos 6460
      pos 6589
      pos 6719
      pos 7117
      pos 7138
    doc 14
      freq 32
      pos 360
      pos 415
      pos 702
      pos 858
      pos 861
      pos 880
      pos 884
      pos 1078
      pos 1200
      pos 1251
      pos 1292
      pos 1358
      pos 1533
      pos 1536
      pos 1776
      pos 1836
      pos 1923
      pos 2020
      pos 2035
      pos 2042
      pos 2120
      pos 2319
      pos 2335
      pos 2527
      pos 2742
      pos 2829
      pos 2877
      pos 2880
      pos 2936
      pos 2945
      pos 5583
      pos 5604
    doc 15
      freq 24
      pos 360
      pos 416
      pos 536
      pos 548
      pos 615
      pos 675
      pos 806
      pos 854
      pos 1041
      pos 1125
      pos 1417
      pos 2138
      pos 2243
      pos 2562
      pos 2762
      pos 2764
      pos 2816
      pos 2829
      pos 3105
      pos 3204
      pos 3717
      pos 3822
      pos 4102
      pos 4123
    doc 16
      freq 21
      pos 245
      pos 252
      pos 260
      pos 364
      pos 485
      pos 519
      pos 581
      pos 639
      pos 666
      pos 710
      pos 780
      pos 1164
      pos 1173
      pos 1294
      pos 1559
      pos 1883
      pos 1885
      pos 1906
      pos 2479
      pos 2713
      pos 2734
    doc 17
      freq 7
      pos 195
      pos 197
      pos 290
      pos 1419
      pos 1745
      pos 2437
      pos 2458
    doc 18
      freq 18
      pos 323
      pos 326
      pos 405
      pos 454
      pos 593
      pos 595
      pos 879
      pos 882
      pos 1085
      pos 1093
      pos 1101
      pos 1170
      pos 1260
      pos 1580
      pos 1633
      pos 1962
      pos 2225
      pos 2246
    skipList 
      level 0
        skipDoc 7
        skipDocFP 403411
        impacts 
          impact 
            freq 18
            norm 100
          impact 
            freq 40
            norm 101
          impact 
            freq 93
            norm 108
        impactsEnd 
        skipDoc 15
        skipDocFP 409054
        impacts 
          impact 
            freq 17
            norm 95
          impact 
            freq 24
            norm 104
          impact 
            freq 32
            norm 107
          impact 
            freq 49
            norm 109
          impact 
            freq 85
            norm 113
        impactsEnd 
  term asaed
    doc 13
      freq 2
      pos 6862
      pos 6961
  term asafcvwegtj7
    doc 10
      freq 1
      pos 6239
  term ascertain
    doc 0
      freq 1
      pos 10258
    doc 10
      freq 1
      pos 4701
  term ascii
    doc 7
      freq 1
      pos 1837
    doc 11
      freq 4
      pos 1011
      pos 1736
      pos 3962
      pos 4621
    doc 14
      freq 15
      pos 627
      pos 832
      pos 1034
      pos 1525
      pos 1686
      pos 1919
      pos 1929
      pos 1936
      pos 2068
      pos 2195
      pos 2205
      pos 2255
      pos 2927
      pos 3567
      pos 4535
    doc 16
      freq 2
      pos 2034
      pos 2214
    doc 18
      freq 1
      pos 1354
  term asd834rk423
    doc 11
      freq 1
      pos 5477
  term asdfhj
    doc 11
      freq 1
      pos 5955
  term asdfnqwo34rq23i34jrjasdcnl23nrlknsdf
    doc 11
      freq 1
      pos 2574
  term asdfwrn23
    doc 11
      freq 1
      pos 5476
  term aseem
    doc 11
      freq 1
      pos 9465
  term aside
    doc 10
      freq 1
      pos 1194
  term ask
    doc 15
      freq 1
      pos 948
  term asked
    doc 2
      freq 1
      pos 1763
  term asking
    doc 12
      freq 1
      pos 2380
    doc 18
      freq 1
      pos 328
  term asks
    doc 12
      freq 1
      pos 2904
  term asn
    doc 0
      freq 2
      pos 2039
      pos 2074
    doc 17
      freq 6
      pos 462
      pos 479
      pos 485
      pos 2104
      pos 2159
      pos 2166
  term asn1
    doc 17
      freq 2
      pos 464
      pos 2090
  term asnvv328qv0p9dohd8uvareep65uc9
    doc 11
      freq 1
      pos 10247
  term aspect
    doc 10
      freq 1
      pos 11408
    doc 11
      freq 1
      pos 570
    doc 15
      freq 1
      pos 142
  term aspects
    doc 0
      freq 1
      pos 16539
    doc 2
      freq 1
      pos 2083
    doc 5
      freq 1
      pos 946
    doc 12
      freq 1
      pos 7360
    doc 13
      freq 1
      pos 3524
    doc 15
      freq 1
      pos 3765
  term aspires
    doc 10
      freq 1
      pos 861
  term assad
    doc 11
      freq 1
      pos 9468
  term assert
    doc 10
      freq 7
      pos 1158
      pos 1463
      pos 1869
      pos 2063
      pos 3743
      pos 10839
      pos 13056
  term asserted
    doc 10
      freq 8
      pos 1036
      pos 1484
      pos 2868
      pos 2959
      pos 8053
      pos 8064
      pos 8100
      pos 13303
  term asserting
    doc 10
      freq 1
      pos 1965
  term assertion
    doc 10
      freq 2
      pos 1420
      pos 8059
  term assess
    doc 6
      freq 1
      pos 473
    doc 17
      freq 1
      pos 127
  term asset
    doc 15
      freq 1
      pos 3650
  term assign
    doc 0
      freq 1
      pos 2431
    doc 4
      freq 1
      pos 969
    doc 15
      freq 1
      pos 3208
  term assigned
    doc 0
      freq 3
      pos 8953
      pos 12844
      pos 15819
    doc 1
      freq 5
      pos 1688
      pos 2517
      pos 2912
      pos 3737
      pos 4157
    doc 2
      freq 2
      pos 3419
      pos 5582
    doc 3
      freq 1
      pos 5565
    doc 4
      freq 5
      pos 2529
      pos 4769
      pos 4939
      pos 5094
      pos 5122
    doc 5
      freq 2
      pos 3789
      pos 4005
    doc 8
      freq 9
      pos 521
      pos 568
      pos 851
      pos 899
      pos 1177
      pos 1224
      pos 1358
      pos 1405
      pos 1547
    doc 10
      freq 2
      pos 6197
      pos 6825
    doc 12
      freq 2
      pos 2547
      pos 6124
    doc 17
      freq 2
      pos 588
      pos 1968
    skipList 
      level 0
        skipDoc 10
        skipDocFP 418603
        impacts 
          impact 
            freq 9
            norm 97
        impactsEnd 
  term assigning
    doc 1
      freq 1
      pos 1811
    doc 4
      freq 1
      pos 5026
  term assignment
    doc 1
      freq 4
      pos 1880
      pos 1897
      pos 7776
      pos 7826
    doc 2
      freq 1
      pos 1268
    doc 4
      freq 3
      pos 946
      pos 4918
      pos 5004
    doc 7
      freq 1
      pos 2467
    doc 8
      freq 1
      pos 589
    doc 12
      freq 3
      pos 6031
      pos 6066
      pos 6156
    doc 15
      freq 1
      pos 2549
  term assignments
    doc 4
      freq 11
      pos 251
      pos 254
      pos 953
      pos 4753
      pos 4863
      pos 4945
      pos 4969
      pos 5051
      pos 5059
      pos 5064
      pos 5912
    doc 8
      freq 3
      pos 913
      pos 1238
      pos 1419
    doc 10
      freq 5
      pos 11520
      pos 11623
      pos 11718
      pos 11819
      pos 11913
    doc 16
      freq 1
      pos 1663
  term assist
    doc 0
      freq 1
      pos 5254
    doc 2
      freq 2
      pos 1274
      pos 1695
  term assistanc
    doc 2
      freq 2
      pos 1711
      pos 4460
  term assistants
    doc 13
      freq 1
      pos 915
  term assisting
    doc 13
      freq 1
      pos 3376
    doc 15
      freq 1
      pos 3531
  term assists
    doc 10
      freq 1
      pos 2270
  term associat
    doc 1
      freq 2
      pos 1438
      pos 8840
  term associated
    doc 0
      freq 14
      pos 726
      pos 829
      pos 881
      pos 931
      pos 1283
      pos 1297
      pos 1307
      pos 1331
      pos 1343
      pos 1354
      pos 2212
      pos 4443
      pos 5689
      pos 9512
    doc 1
      freq 4
      pos 3161
      pos 4502
      pos 7128
      pos 8863
    doc 3
      freq 2
      pos 371
      pos 1814
    doc 5
      freq 1
      pos 685
    doc 8
      freq 4
      pos 160
      pos 1637
      pos 1646
      pos 1655
    doc 9
      freq 2
      pos 798
      pos 1419
    doc 10
      freq 4
      pos 2905
      pos 2935
      pos 3288
      pos 10556
    doc 12
      freq 1
      pos 4976
    doc 13
      freq 1
      pos 1884
    doc 17
      freq 2
      pos 693
      pos 1631
    skipList 
      level 0
        skipDoc 12
        skipDocFP 420858
        impacts 
          impact 
            freq 2
            norm 95
          impact 
            freq 4
            norm 97
          impact 
            freq 14
            norm 120
        impactsEnd 
  term association
    doc 1
      freq 2
      pos 3564
      pos 3601
    doc 2
      freq 2
      pos 2290
      pos 3414
    doc 3
      freq 1
      pos 5177
    doc 5
      freq 1
      pos 397
    doc 9
      freq 1
      pos 1600
    doc 10
      freq 3
      pos 605
      pos 626
      pos 10355
    doc 12
      freq 3
      pos 5617
      pos 5636
      pos 5658
    doc 13
      freq 1
      pos 1473
    doc 15
      freq 2
      pos 2559
      pos 2585
    skipList 
      level 0
        skipDoc 13
        skipDocFP 421911
        impacts 
          impact 
            freq 1
            norm 95
          impact 
            freq 2
            norm 108
          impact 
            freq 3
            norm 113
        impactsEnd 
  term associations
    doc 0
      freq 1
      pos 509
  term assum
    doc 1
      freq 2
      pos 1215
      pos 1229
    doc 7
      freq 1
      pos 345
    doc 10
      freq 2
      pos 9691
      pos 11432
    doc 12
      freq 2
      pos 2148
      pos 5976
    doc 14
      freq 2
      pos 622
      pos 2788
  term assumed
    doc 3
      freq 2
      pos 428
      pos 2957
    doc 5
      freq 1
      pos 3028
    doc 11
      freq 1
      pos 9221
    doc 12
      freq 2
      pos 4269
      pos 5613
    doc 14
      freq 1
      pos 2614
  term assumes
    doc 3
      freq 1
      pos 385
    doc 5
      freq 2
      pos 181
      pos 3341
    doc 6
      freq 1
      pos 1193
    doc 10
      freq 2
      pos 1510
      pos 11043
    doc 13
      freq 1
      pos 3787
    doc 14
      freq 1
      pos 2842
  term assuming
    doc 5
      freq 1
      pos 983
    doc 12
      freq 1
      pos 5645
    doc 15
      freq 1
      pos 2204
    doc 18
      freq 1
      pos 1118
  term assumption
    doc 10
      freq 2
      pos 1522
      pos 9193
    doc 12
      freq 1
      pos 7780
    doc 13
      freq 1
      pos 3878
    doc 14
      freq 1
      pos 1362
  term assumptions
    doc 12
      freq 1
      pos 941
  term assur
    doc 1
      freq 1
      pos 8335
    doc 6
      freq 1
      pos 361
  term assuranc
    doc 9
      freq 1
      pos 485
    doc 10
      freq 16
      pos 632
      pos 660
      pos 1540
      pos 1583
      pos 7917
      pos 9117
      pos 9124
      pos 9395
      pos 10017
      pos 11013
      pos 11031
      pos 12880
      pos 12931
      pos 12952
      pos 12969
      pos 12988
    doc 17
      freq 2
      pos 1587
      pos 1630
  term assurances
    doc 0
      freq 1
      pos 17433
    doc 1
      freq 1
      pos 9814
    doc 2
      freq 1
      pos 6611
    doc 3
      freq 1
      pos 6163
    doc 4
      freq 1
      pos 6318
    doc 5
      freq 1
      pos 4648
    doc 6
      freq 1
      pos 3448
    doc 7
      freq 1
      pos 3153
    doc 8
      freq 1
      pos 2370
    doc 9
      freq 1
      pos 2015
    doc 10
      freq 3
      pos 12900
      pos 12907
      pos 13676
    doc 11
      freq 1
      pos 10837
    doc 12
      freq 1
      pos 9687
    doc 13
      freq 1
      pos 7302
    doc 14
      freq 1
      pos 5768
    doc 15
      freq 1
      pos 4287
    doc 16
      freq 1
      pos 2898
    doc 17
      freq 1
      pos 2622
    doc 18
      freq 1
      pos 2410
    skipList 
      level 0
        skipDoc 7
        skipDocFP 424376
        impacts 
          impact 
            freq 1
            norm 100
        impactsEnd 
        skipDoc 15
        skipDocFP 424681
        impacts 
          impact 
            freq 1
            norm 95
          impact 
            freq 3
            norm 116
        impactsEnd 
  term assured
    doc 5
      freq 1
      pos 720
  term assuring
    doc 10
      freq 1
      pos 105
  term astring
    doc 16
      freq 2
      pos 1496
      pos 1537
  term asymmetric
    doc 5
      freq 1
      pos 838
  term asynchronous
    doc 1
      freq 1
      pos 113
    doc 13
      freq 1
      pos 851
  term at
    doc 0
      freq 83
      pos 1117
      pos 2341
      pos 2584
      pos 2831
      pos 2880
      pos 3056
      pos 3581
      pos 4060
      pos 4495
      pos 4569
      pos 4776
      pos 4846
      pos 4878
      pos 4891
      pos 4903
      pos 5060
      pos 5159
      pos 5189
      pos 5213
      pos 5571
      pos 6486
      pos 6740
      pos 6859
      pos 6866
      pos 6884
      pos 7003
      pos 7040
      pos 7132
      pos 7175
      pos 7697
      pos 8233
      pos 8263
      pos 8286
      pos 8315
      pos 8376
      pos 8439
      pos 8460
      pos 8470
      pos 8475
      pos 8483
      pos 8507
      pos 8532
      pos 8537
      pos 8545
      pos 8565
      pos 8589
      pos 8594
      pos 8602
      pos 8623
      pos 8655
      pos 8680
      pos 8700
      pos 8725
      pos 8745
      pos 8767
      pos 8785
      pos 9214
      pos 9223
      pos 11808
      pos 12890
      pos 12912
      pos 13144
      pos 13166
      pos 13246
      pos 13268
      pos 13463
      pos 13485
      pos 13561
      pos 13583
      pos 13653
      pos 13675
      pos 13755
      pos 13777
      pos 13828
      pos 13850
      pos 13900
      pos 13934
      pos 14040
      pos 14062
      pos 14169
      pos 14191
      pos 17478
      pos 17522
    doc 1
      freq 27
      pos 498
      pos 1139
      pos 1142
      pos 1147
      pos 1398
      pos 1581
      pos 1737
      pos 1750
      pos 2673
      pos 2760
      pos 3090
      pos 3100
      pos 3439
      pos 3450
      pos 3559
      pos 3983
      pos 4347
      pos 4436
      pos 5159
      pos 5994
      pos 6957
      pos 6993
      pos 7665
      pos 8049
      pos 8607
      pos 9859
      pos 9903
    doc 2
      freq 18
      pos 184
      pos 380
      pos 1130
      pos 1448
      pos 3638
      pos 3658
      pos 3797
      pos 4162
      pos 4289
      pos 4297
      pos 5153
      pos 5266
      pos 5666
      pos 5774
      pos 5779
      pos 6342
      pos 6656
      pos 6700
    doc 3
      freq 34
      pos 795
      pos 798
      pos 802
      pos 916
      pos 924
      pos 947
      pos 959
      pos 1140
      pos 1156
      pos 1489
      pos 1764
      pos 1963
      pos 2067
      pos 2642
      pos 2691
      pos 2785
      pos 2861
      pos 3070
      pos 3076
      pos 3902
      pos 3971
      pos 3987
      pos 3999
      pos 4039
      pos 5048
      pos 5184
      pos 5243
      pos 5269
      pos 5303
      pos 5322
      pos 5479
      pos 5566
      pos 6208
      pos 6252
    doc 4
      freq 7
      pos 1020
      pos 1386
      pos 4712
      pos 4929
      pos 5061
      pos 6363
      pos 6407
    doc 5
      freq 6
      pos 2341
      pos 2936
      pos 3306
      pos 3333
      pos 4693
      pos 4737
    doc 6
      freq 22
      pos 151
      pos 243
      pos 924
      pos 947
      pos 1041
      pos 1172
      pos 1253
      pos 1260
      pos 1265
      pos 1351
      pos 1402
      pos 1479
      pos 1586
      pos 1767
      pos 1821
      pos 2185
      pos 2230
      pos 2269
      pos 2727
      pos 3257
      pos 3493
      pos 3537
    doc 7
      freq 5
      pos 1400
      pos 1455
      pos 1609
      pos 3198
      pos 3242
    doc 8
      freq 2
      pos 2415
      pos 2459
    doc 9
      freq 4
      pos 650
      pos 725
      pos 2060
      pos 2104
    doc 10
      freq 10
      pos 5657
      pos 6928
      pos 8548
      pos 9146
      pos 9317
      pos 9483
      pos 9494
      pos 10141
      pos 13721
      pos 13765
    doc 11
      freq 15
      pos 314
      pos 614
      pos 922
      pos 930
      pos 936
      pos 1858
      pos 4189
      pos 5711
      pos 6845
      pos 7325
      pos 8265
      pos 9183
      pos 9371
      pos 10882
      pos 10926
    doc 12
      freq 38
      pos 624
      pos 684
      pos 735
      pos 1017
      pos 1043
      pos 1117
      pos 1544
      pos 1879
      pos 2167
      pos 2419
      pos 2778
      pos 3178
      pos 3432
      pos 3565
      pos 3924
      pos 3945
      pos 4401
      pos 4531
      pos 4774
      pos 5216
      pos 5234
      pos 5252
      pos 5368
      pos 5481
      pos 5551
      pos 6201
      pos 6210
      pos 6330
      pos 6412
      pos 6956
      pos 8169
      pos 8191
      pos 8435
      pos 8927
      pos 9146
      pos 9248
      pos 9732
      pos 9776
    doc 13
      freq 5
      pos 4524
      pos 4860
      pos 6172
      pos 7347
      pos 7391
    doc 14
      freq 5
      pos 1115
      pos 1824
      pos 2565
      pos 5813
      pos 5857
    doc 15
      freq 6
      pos 2310
      pos 2412
      pos 3137
      pos 3185
      pos 4332
      pos 4376
    doc 16
      freq 3
      pos 1660
      pos 2943
      pos 2987
    doc 17
      freq 3
      pos 425
      pos 2667
      pos 2711
    doc 18
      freq 7
      pos 508
      pos 737
      pos 830
      pos 977
      pos 1954
      pos 2455
      pos 2499
    skipList 
      level 0
        skipDoc 7
        skipDocFP 425839
        impacts 
          impact 
            freq 5
            norm 100
          impact 
            freq 22
            norm 101
          impact 
            freq 34
            norm 107
          impact 
            freq 83
            norm 120
        impactsEnd 
        skipDoc 15
        skipDocFP 429069
        impacts 
          impact 
            freq 4
            norm 95
          impact 
            freq 6
            norm 104
          impact 
            freq 38
            norm 113
        impactsEnd 
  term atcp
    doc 7
      freq 2
      pos 758
      pos 2128
  term atkinson
    doc 4
      freq 1
      pos 5371
  term atlant
    doc 6
      freq 1
      pos 3208
    doc 10
      freq 1
      pos 3049
  term atlanta.cer
    doc 10
      freq 1
      pos 6662
  term atlanta.example.com
    doc 10
      freq 32
      pos 454
      pos 930
      pos 3033
      pos 6199
      pos 6290
      pos 6331
      pos 6341
      pos 6365
      pos 6382
      pos 6390
      pos 6435
      pos 6481
      pos 6497
      pos 6507
      pos 6515
      pos 6567
      pos 6616
      pos 6626
      pos 6650
      pos 6661
      pos 6682
      pos 6690
      pos 6705
      pos 6725
      pos 6975
      pos 6997
      pos 7112
      pos 7134
      pos 7233
      pos 7325
      pos 7347
      pos 12306
  term atlanta.example.org
    doc 10
      freq 1
      pos 6312
  term atm
    doc 1
      freq 7
      pos 438
      pos 1077
      pos 1082
      pos 1567
      pos 1579
      pos 9048
      pos 9064
    doc 7
      freq 2
      pos 2663
      pos 2669
    doc 8
      freq 18
      pos 638
      pos 643
      pos 645
      pos 649
      pos 674
      pos 681
      pos 683
      pos 690
      pos 697
      pos 704
      pos 706
      pos 713
      pos 715
      pos 720
      pos 1025
      pos 1027
      pos 1937
      pos 1953
  term atm3vpi4vci5
    doc 1
      freq 1
      pos 4488
  term atomic
    doc 13
      freq 3
      pos 1248
      pos 1335
      pos 1404
  term attached
    doc 3
      freq 2
      pos 1592
      pos 2394
    doc 4
      freq 1
      pos 1917
    doc 14
      freq 1
      pos 1900
  term attachment
    doc 1
      freq 28
      pos 262
      pos 1016
      pos 1019
      pos 2027
      pos 2780
      pos 3062
      pos 3108
      pos 3164
      pos 3175
      pos 3249
      pos 3255
      pos 3261
      pos 3266
      pos 3289
      pos 3486
      pos 3491
      pos 3496
      pos 4208
      pos 4484
      pos 4508
      pos 4836
      pos 4993
      pos 5366
      pos 8443
      pos 8464
      pos 8473
      pos 8787
      pos 8845
    doc 2
      freq 1
      pos 3238
    doc 3
      freq 10
      pos 623
      pos 626
      pos 809
      pos 1435
      pos 1762
      pos 1905
      pos 2514
      pos 2569
      pos 2760
      pos 2789
    doc 8
      freq 12
      pos 138
      pos 142
      pos 148
      pos 1133
      pos 1136
      pos 1148
      pos 1291
      pos 1316
      pos 1329
      pos 1486
      pos 1599
      pos 1607
    doc 15
      freq 1
      pos 3742
    doc 16
      freq 3
      pos 1754
      pos 2139
      pos 2150
  term attachments
    doc 16
      freq 1
      pos 2135
  term attack
    doc 0
      freq 2
      pos 16195
      pos 16542
    doc 4
      freq 10
      pos 4162
      pos 4213
      pos 4298
      pos 4417
      pos 4470
      pos 4515
      pos 4550
      pos 4593
      pos 5439
      pos 5858
    doc 5
      freq 12
      pos 307
      pos 311
      pos 317
      pos 321
      pos 2977
      pos 3005
      pos 3162
      pos 3204
      pos 3285
      pos 3405
      pos 3469
      pos 3625
    doc 10
      freq 3
      pos 8871
      pos 9366
      pos 9492
    doc 11
      freq 1
      pos 8444
    doc 14
      freq 1
      pos 5299
    doc 15
      freq 1
      pos 1731
    doc 18
      freq 3
      pos 483
      pos 1711
      pos 1727
    skipList 
      level 0
        skipDoc 18
        skipDocFP 434065
        impacts 
          impact 
            freq 3
            norm 97
          impact 
            freq 12
            norm 104
        impactsEnd 
  term attacker
    doc 0
      freq 1
      pos 16019
    doc 10
      freq 8
      pos 8676
      pos 8732
      pos 8770
      pos 8856
      pos 8907
      pos 8994
      pos 9261
      pos 12991
    doc 14
      freq 1
      pos 2744
    doc 15
      freq 1
      pos 1734
    doc 17
      freq 1
      pos 1416
    doc 18
      freq 1
      pos 1922
  term attacker's
    doc 10
      freq 2
      pos 8888
      pos 8934
  term attackers
    doc 10
      freq 2
      pos 814
      pos 9853
    doc 13
      freq 1
      pos 6388
  term attacks
    doc 1
      freq 1
      pos 8722
    doc 4
      freq 10
      pos 236
      pos 4098
      pos 4106
      pos 4125
      pos 4362
      pos 4582
      pos 4651
      pos 5443
      pos 5865
      pos 6015
    doc 5
      freq 2
      pos 3490
      pos 3589
    doc 9
      freq 3
      pos 440
      pos 1130
      pos 1569
    doc 10
      freq 11
      pos 5301
      pos 8279
      pos 8417
      pos 8454
      pos 8584
      pos 8901
      pos 9874
      pos 9960
      pos 10180
      pos 10186
      pos 10202
    doc 11
      freq 2
      pos 9341
      pos 9377
    doc 13
      freq 12
      pos 329
      pos 333
      pos 6365
      pos 6424
      pos 6447
      pos 6491
      pos 6527
      pos 6600
      pos 6641
      pos 6668
      pos 6687
      pos 6718
    doc 18
      freq 1
      pos 1749
    skipList 
      level 0
        skipDoc 18
        skipDocFP 435525
        impacts 
          impact 
            freq 3
            norm 95
          impact 
            freq 10
            norm 108
          impact 
            freq 12
            norm 109
        impactsEnd 
  term attempt
    doc 0
      freq 4
      pos 3103
      pos 3269
      pos 13872
      pos 17445
    doc 1
      freq 2
      pos 5618
      pos 9826
    doc 2
      freq 1
      pos 6623
    doc 3
      freq 1
      pos 6175
    doc 4
      freq 2
      pos 4358
      pos 6330
    doc 5
      freq 1
      pos 4660
    doc 6
      freq 2
      pos 2142
      pos 3460
    doc 7
      freq 2
      pos 1454
      pos 3165
    doc 8
      freq 1
      pos 2382
    doc 9
      freq 2
      pos 1539
      pos 2027
    doc 10
      freq 4
      pos 816
      pos 9440
      pos 10111
      pos 13688
    doc 11
      freq 10
      pos 668
      pos 681
      pos 4208
      pos 5114
      pos 5431
      pos 6112
      pos 6537
      pos 7322
      pos 9383
      pos 10849
    doc 12
      freq 3
      pos 3622
      pos 4702
      pos 9699
    doc 13
      freq 1
      pos 7314
    doc 14
      freq 1
      pos 5780
    doc 15
      freq 1
      pos 4299
    doc 16
      freq 1
      pos 2910
    doc 17
      freq 1
      pos 2634
    doc 18
      freq 2
      pos 1738
      pos 2422
    skipList 
      level 0
        skipDoc 7
        skipDocFP 436644
        impacts 
          impact 
            freq 2
            norm 100
          impact 
            freq 4
            norm 120
        impactsEnd 
        skipDoc 15
        skipDocFP 437055
        impacts 
          impact 
            freq 2
            norm 95
          impact 
            freq 3
            norm 113
          impact 
            freq 10
            norm 114
        impactsEnd 
  term attempted
    doc 0
      freq 1
      pos 7528
    doc 5
      freq 1
      pos 3386
    doc 10
      freq 1
      pos 9717
    doc 12
      freq 1
      pos 2708
  term attempting
    doc 1
      freq 1
      pos 7646
    doc 10
      freq 1
      pos 10093
    doc 11
      freq 2
      pos 5278
      pos 6423
  term attempts
    doc 0
      freq 1
      pos 5317
  term attemptstoexceedmaximumsequencenumber
    doc 0
      freq 1
      pos 7537
  term attend
    doc 2
      freq 1
      pos 1189
  term attending
    doc 2
      freq 1
      pos 930
  term attention
    doc 0
      freq 1
      pos 17492
    doc 1
      freq 1
      pos 9873
    doc 2
      freq 1
      pos 6670
    doc 3
      freq 1
      pos 6222
    doc 4
      freq 1
      pos 6377
    doc 5
      freq 1
      pos 4707
    doc 6
      freq 1
      pos 3507
    doc 7
      freq 2
      pos 1741
      pos 3212
    doc 8
      freq 1
      pos 2429
    doc 9
      freq 1
      pos 2074
    doc 10
      freq 1
      pos 13735
    doc 11
      freq 2
      pos 1365
      pos 10896
    doc 12
      freq 1
      pos 9746
    doc 13
      freq 1
      pos 7361
    doc 14
      freq 1
      pos 5827
    doc 15
      freq 1
      pos 4346
    doc 16
      freq 1
      pos 2957
    doc 17
      freq 1
      pos 2681
    doc 18
      freq 1
      pos 2469
    skipList 
      level 0
        skipDoc 7
        skipDocFP 438783
        impacts 
          impact 
            freq 2
            norm 100
        impactsEnd 
        skipDoc 15
        skipDocFP 439103
        impacts 
          impact 
            freq 1
            norm 95
          impact 
            freq 2
            norm 114
        impactsEnd 
  term attractiv
    doc 10
      freq 2
      pos 4375
      pos 8822
  term attribut
    doc 0
      freq 4
      pos 2959
      pos 16331
      pos 16585
      pos 16619
    doc 1
      freq 1
      pos 3282
    doc 2
      freq 4
      pos 1544
      pos 1569
      pos 1584
      pos 6179
    doc 5
      freq 4
      pos 3715
      pos 3764
      pos 3937
      pos 3960
    doc 7
      freq 1
      pos 2884
    doc 17
      freq 13
      pos 18
      pos 94
      pos 103
      pos 230
      pos 254
      pos 300
      pos 353
      pos 678
      pos 1019
      pos 1073
      pos 1258
      pos 2081
      pos 2140
  term attributes
    doc 0
      freq 25
      pos 461
      pos 621
      pos 725
      pos 828
      pos 880
      pos 930
      pos 939
      pos 1276
      pos 1282
      pos 1296
      pos 1306
      pos 1330
      pos 1342
      pos 1353
      pos 16186
      pos 16250
      pos 16278
      pos 16365
      pos 16386
      pos 16416
      pos 16451
      pos 16493
      pos 16647
      pos 16672
      pos 16689
    doc 1
      freq 1
      pos 772
    doc 2
      freq 7
      pos 1496
      pos 1527
      pos 1555
      pos 1659
      pos 3080
      pos 5067
      pos 6160
    doc 5
      freq 5
      pos 3481
      pos 3704
      pos 3787
      pos 3822
      pos 4003
    doc 17
      freq 17
      pos 134
      pos 347
      pos 382
      pos 405
      pos 564
      pos 674
      pos 752
      pos 1299
      pos 1316
      pos 1325
      pos 1350
      pos 1530
      pos 1621
      pos 1645
      pos 1864
      pos 1878
      pos 2285
  term atypical
    doc 11
      freq 2
      pos 419
      pos 7415
  term au3ao48hzk4gewgzn2ortubag
    doc 10
      freq 1
      pos 12488
  term audienc
    doc 2
      freq 1
      pos 4275
    doc 13
      freq 3
      pos 679
      pos 1049
      pos 4057
  term audiences
    doc 13
      freq 2
      pos 722
      pos 1896
  term audio
    doc 10
      freq 3
      pos 6395
      pos 6532
      pos 6695
    doc 11
      freq 22
      pos 1550
      pos 2268
      pos 3186
      pos 3419
      pos 4062
      pos 4327
      pos 4508
      pos 4722
      pos 5213
      pos 5370
      pos 5518
      pos 5678
      pos 5998
      pos 6222
      pos 6908
      pos 7246
      pos 7887
      pos 7891
      pos 8202
      pos 8531
      pos 9126
      pos 9303
    doc 13
      freq 5
      pos 2877
      pos 2894
      pos 2917
      pos 3112
      pos 3162
  term augmented
    doc 10
      freq 1
      pos 13190
    doc 13
      freq 1
      pos 985
    doc 16
      freq 2
      pos 1418
      pos 2611
  term august
    doc 2
      freq 5
      pos 2348
      pos 3014
      pos 3116
      pos 3349
      pos 5337
    doc 3
      freq 1
      pos 4679
    doc 4
      freq 1
      pos 5363
    doc 5
      freq 1
      pos 4180
    doc 8
      freq 1
      pos 1828
    doc 10
      freq 42
      pos 17
      pos 176
      pos 400
      pos 791
      pos 1254
      pos 1705
      pos 2092
      pos 2518
      pos 2973
      pos 3377
      pos 3789
      pos 4188
      pos 4599
      pos 4943
      pos 5403
      pos 5768
      pos 6058
      pos 6276
      pos 6529
      pos 6784
      pos 6970
      pos 7274
      pos 7604
      pos 8036
      pos 8470
      pos 8990
      pos 9480
      pos 9945
      pos 10335
      pos 10791
      pos 11208
      pos 11546
      pos 11841
      pos 12098
      pos 12389
      pos 12536
      pos 12700
      pos 12835
      pos 13085
      pos 13210
      pos 13335
      pos 13464
    doc 12
      freq 6
      pos 7096
      pos 7169
      pos 7223
      pos 7257
      pos 7646
      pos 7857
  term aura
    doc 9
      freq 1
      pos 1742
    doc 12
      freq 1
      pos 7545
  term austein
    doc 12
      freq 3
      pos 6781
      pos 6815
      pos 7240
    doc 14
      freq 1
      pos 5431
    doc 18
      freq 3
      pos 2062
      pos 2083
      pos 2106
  term aut
    doc 13
      freq 8
      pos 5813
      pos 5830
      pos 5856
      pos 5870
      pos 5896
      pos 5922
      pos 5964
      pos 5979
  term auth
    doc 0
      freq 2
      pos 8161
      pos 8199
    doc 4
      freq 5
      pos 4042
      pos 4173
      pos 4223
      pos 4338
      pos 5383
    doc 10
      freq 1
      pos 10305
  term authenticat
    doc 1
      freq 1
      pos 8297
    doc 5
      freq 1
      pos 3091
    doc 10
      freq 8
      pos 558
      pos 1002
      pos 1290
      pos 2200
      pos 2555
      pos 2687
      pos 2988
      pos 11053
    doc 12
      freq 1
      pos 5148
    doc 13
      freq 3
      pos 5820
      pos 5837
      pos 5971
    doc 16
      freq 1
      pos 990
  term authenticated
    doc 4
      freq 1
      pos 4035
    doc 5
      freq 3
      pos 2605
      pos 3137
      pos 4245
    doc 9
      freq 1
      pos 950
    doc 10
      freq 10
      pos 21
      pos 413
      pos 1232
      pos 1298
      pos 1318
      pos 1974
      pos 2055
      pos 2647
      pos 7942
      pos 13175
    doc 13
      freq 4
      pos 5811
      pos 5907
      pos 5935
      pos 6413
    doc 14
      freq 1
      pos 104
    doc 16
      freq 4
      pos 877
      pos 934
      pos 980
      pos 1026
  term authenticates
    doc 10
      freq 6
      pos 1278
      pos 1359
      pos 1369
      pos 1853
      pos 6413
      pos 7017
  term authenticating
    doc 9
      freq 2
      pos 505
      pos 1142
    doc 10
      freq 3
      pos 897
      pos 2152
      pos 13060
    doc 12
      freq 2
      pos 4711
      pos 6975
  term authentication
    doc 0
      freq 9
      pos 7385
      pos 7398
      pos 7418
      pos 7431
      pos 8205
      pos 13426
      pos 13512
      pos 16160
      pos 16744
    doc 1
      freq 2
      pos 8625
      pos 8654
    doc 2
      freq 15
      pos 80
      pos 227
      pos 288
      pos 2316
      pos 2807
      pos 2962
      pos 3027
      pos 3126
      pos 3143
      pos 3151
      pos 3173
      pos 3276
      pos 3292
      pos 3341
      pos 4851
    doc 4
      freq 10
      pos 227
      pos 4023
      pos 4039
      pos 4170
      pos 4220
      pos 4233
      pos 4319
      pos 4336
      pos 5387
      pos 5838
    doc 5
      freq 33
      pos 23
      pos 93
      pos 97
      pos 138
      pos 146
      pos 167
      pos 209
      pos 439
      pos 460
      pos 477
      pos 512
      pos 601
      pos 770
      pos 897
      pos 1015
      pos 2158
      pos 2777
      pos 2867
      pos 2989
      pos 3018
      pos 3060
      pos 3068
      pos 3096
      pos 3249
      pos 3270
      pos 3392
      pos 3512
      pos 3539
      pos 3639
      pos 4199
      pos 4203
      pos 4224
      pos 4269
    doc 7
      freq 9
      pos 807
      pos 1098
      pos 2217
      pos 2415
      pos 2602
      pos 2607
      pos 2720
      pos 2801
      pos 2809
    doc 9
      freq 3
      pos 996
      pos 1029
      pos 1271
    doc 10
      freq 106
      pos 196
      pos 290
      pos 509
      pos 568
      pos 887
      pos 1260
      pos 1337
      pos 1386
      pos 1507
      pos 1560
      pos 1652
      pos 1770
      pos 1844
      pos 1851
      pos 1860
      pos 2095
      pos 2109
      pos 2112
      pos 2131
      pos 2211
      pos 2242
      pos 2273
      pos 2311
      pos 2321
      pos 2342
      pos 2355
      pos 2389
      pos 2448
      pos 2468
      pos 2500
      pos 2523
      pos 2552
      pos 2567
      pos 2574
      pos 2597
      pos 2603
      pos 2651
      pos 2659
      pos 2671
      pos 2740
      pos 2751
      pos 3050
      pos 3088
      pos 3143
      pos 3206
      pos 3209
      pos 3265
      pos 3301
      pos 3330
      pos 3381
      pos 3574
      pos 3625
      pos 3709
      pos 3725
      pos 4355
      pos 4412
      pos 4550
      pos 4578
      pos 4728
      pos 5033
      pos 5588
      pos 5671
      pos 5683
      pos 5872
      pos 5981
      pos 6318
      pos 6407
      pos 6436
      pos 6568
      pos 6957
      pos 7011
      pos 7040
      pos 7097
      pos 7286
      pos 7632
      pos 7672
      pos 7692
      pos 7804
      pos 7819
      pos 7845
      pos 7872
      pos 7914
      pos 7970
      pos 8019
      pos 8958
      pos 8975
      pos 9002
      pos 9141
      pos 9752
      pos 10014
      pos 10041
      pos 10059
      pos 10098
      pos 10143
      pos 10243
      pos 10284
      pos 10341
      pos 10358
      pos 10524
      pos 10538
      pos 10835
      pos 10845
      pos 10931
      pos 11149
      pos 11157
      pos 11287
    doc 11
      freq 2
      pos 7959
      pos 7985
    doc 12
      freq 6
      pos 4340
      pos 4453
      pos 4534
      pos 4756
      pos 6421
      pos 6469
    doc 13
      freq 5
      pos 311
      pos 2408
      pos 5786
      pos 5920
      pos 6628
    doc 15
      freq 2
      pos 1695
      pos 3929
    skipList 
      level 0
        skipDoc 10
        skipDocFP 445469
        impacts 
          impact 
            freq 3
            norm 95
          impact 
            freq 9
            norm 100
          impact 
            freq 33
            norm 104
          impact 
            freq 106
            norm 116
        impactsEnd 
  term authenticator
    doc 2
      freq 1
      pos 3346
  term author
    doc 2
      freq 1
      pos 3602
  term author's
    doc 2
      freq 1
      pos 6374
    doc 8
      freq 1
      pos 2127
    doc 9
      freq 1
      pos 1762
    doc 16
      freq 1
      pos 2648
  term authoritativ
    doc 10
      freq 1
      pos 4169
    doc 12
      freq 6
      pos 1120
      pos 3181
      pos 4735
      pos 5819
      pos 6375
      pos 9173
    doc 18
      freq 7
      pos 124
      pos 949
      pos 1043
      pos 1143
      pos 1264
      pos 1660
      pos 1703
  term authorities
    doc 10
      freq 6
      pos 6136
      pos 10849
      pos 10876
      pos 10890
      pos 10905
      pos 10915
    doc 17
      freq 1
      pos 2024
  term authority
    doc 2
      freq 2
      pos 867
      pos 878
    doc 10
      freq 6
      pos 4091
      pos 4138
      pos 6077
      pos 7960
      pos 10951
      pos 11784
    doc 12
      freq 4
      pos 950
      pos 4936
      pos 6223
      pos 6288
    doc 17
      freq 2
      pos 173
      pos 354
  term authoriz
    doc 10
      freq 1
      pos 7824
    doc 13
      freq 2
      pos 6206
      pos 6220
  term authorization
    doc 2
      freq 4
      pos 81
      pos 228
      pos 1005
      pos 4853
    doc 9
      freq 3
      pos 960
      pos 1199
      pos 1268
    doc 10
      freq 20
      pos 300
      pos 724
      pos 820
      pos 872
      pos 1071
      pos 1207
      pos 2719
      pos 2772
      pos 2810
      pos 2854
      pos 2943
      pos 3845
      pos 6426
      pos 7030
      pos 11004
      pos 11118
      pos 11138
      pos 11386
      pos 11413
      pos 11428
    doc 11
      freq 6
      pos 443
      pos 7894
      pos 7901
      pos 7942
      pos 7964
      pos 8066
    doc 12
      freq 10
      pos 4544
      pos 5041
      pos 5226
      pos 5378
      pos 5494
      pos 5540
      pos 5571
      pos 5650
      pos 5839
      pos 6908
    doc 13
      freq 5
      pos 6197
      pos 6243
      pos 6309
      pos 6353
      pos 6627
    doc 17
      freq 2
      pos 1875
      pos 2085
  term authorized
    doc 10
      freq 15
      pos 1141
      pos 1156
      pos 1185
      pos 1235
      pos 1329
      pos 1867
      pos 1979
      pos 2536
      pos 3429
      pos 3741
      pos 4440
      pos 4468
      pos 9351
      pos 9389
      pos 13045
    doc 12
      freq 1
      pos 5019
  term authorizing
    doc 9
      freq 2
      pos 111
      pos 700
  term authors
    doc 0
      freq 2
      pos 17195
      pos 17253
    doc 1
      freq 5
      pos 410
      pos 8873
      pos 9184
      pos 9503
      pos 9634
    doc 2
      freq 4
      pos 3357
      pos 3454
      pos 4232
      pos 6431
    doc 3
      freq 2
      pos 5867
      pos 5983
    doc 4
      freq 2
      pos 6042
      pos 6138
    doc 5
      freq 3
      pos 4066
      pos 4396
      pos 4468
    doc 6
      freq 3
      pos 3089
      pos 3178
      pos 3268
    doc 7
      freq 5
      pos 293
      pos 315
      pos 421
      pos 2896
      pos 2973
    doc 8
      freq 1
      pos 2190
    doc 9
      freq 1
      pos 1835
    doc 10
      freq 3
      pos 12104
      pos 13403
      pos 13496
    doc 11
      freq 2
      pos 10524
      pos 10657
    doc 12
      freq 2
      pos 9426
      pos 9507
    doc 13
      freq 3
      pos 6955
      pos 6987
      pos 7122
    doc 14
      freq 3
      pos 5338
      pos 5505
      pos 5588
    doc 15
      freq 4
      pos 3833
      pos 3879
      pos 4014
      pos 4107
    doc 16
      freq 1
      pos 2718
    doc 17
      freq 2
      pos 2365
      pos 2442
    doc 18
      freq 3
      pos 2009
      pos 2157
      pos 2230
    skipList 
      level 0
        skipDoc 7
        skipDocFP 451633
        impacts 
          impact 
            freq 5
            norm 100
        impactsEnd 
        skipDoc 15
        skipDocFP 452205
        impacts 
          impact 
            freq 1
            norm 95
          impact 
            freq 4
            norm 104
        impactsEnd 
  term auto
    doc 1
      freq 4
      pos 2969
      pos 8533
      pos 8543
      pos 8748
  term autoconfiguration
    doc 12
      freq 6
      pos 394
      pos 4247
      pos 4432
      pos 5433
      pos 7081
      pos 7134
    doc 15
      freq 2
      pos 398
      pos 3918
  term autodiscovery
    doc 1
      freq 1
      pos 4358
    doc 8
      freq 1
      pos 2089
  term automat
    doc 12
      freq 1
      pos 5811
  term automated
    doc 6
      freq 1
      pos 2459
    doc 10
      freq 1
      pos 730
  term automatic
    doc 0
      freq 4
      pos 10801
      pos 10840
      pos 11351
      pos 11380
    doc 12
      freq 4
      pos 1403
      pos 1579
      pos 4389
      pos 6382
  term automatically
    doc 0
      freq 3
      pos 2269
      pos 2430
      pos 8952
    doc 1
      freq 1
      pos 5832
    doc 12
      freq 1
      pos 3859
    doc 13
      freq 1
      pos 2978
  term autonomic
    doc 12
      freq 2
      pos 14
      pos 9443
    doc 18
      freq 2
      pos 19
      pos 2176
  term autonomica.s
    doc 12
      freq 1
      pos 9453
    doc 18
      freq 1
      pos 2187
  term autonomous
    doc 12
      freq 1
      pos 1449
  term av3
    doc 11
      freq 1
      pos 10500
  term availability
    doc 6
      freq 2
      pos 363
      pos 2804
    doc 13
      freq 1
      pos 3182
    doc 17
      freq 1
      pos 1576
  term availabl
    doc 0
      freq 3
      pos 13311
      pos 17385
      pos 17439
    doc 1
      freq 3
      pos 4899
      pos 9766
      pos 9820
    doc 2
      freq 4
      pos 601
      pos 6322
      pos 6563
      pos 6617
    doc 3
      freq 3
      pos 5674
      pos 6115
      pos 6169
    doc 4
      freq 2
      pos 6270
      pos 6324
    doc 5
      freq 6
      pos 187
      pos 2193
      pos 2935
      pos 3637
      pos 4600
      pos 4654
    doc 6
      freq 4
      pos 2516
      pos 2797
      pos 3400
      pos 3454
    doc 7
      freq 2
      pos 3105
      pos 3159
    doc 8
      freq 2
      pos 2322
      pos 2376
    doc 9
      freq 2
      pos 1967
      pos 2021
    doc 10
      freq 6
      pos 5656
      pos 5705
      pos 6594
      pos 7310
      pos 13628
      pos 13682
    doc 11
      freq 3
      pos 3758
      pos 10789
      pos 10843
    doc 12
      freq 5
      pos 1172
      pos 3972
      pos 6703
      pos 9639
      pos 9693
    doc 13
      freq 12
      pos 743
      pos 2688
      pos 2957
      pos 3567
      pos 3618
      pos 3753
      pos 4367
      pos 4399
      pos 4762
      pos 6146
      pos 7254
      pos 7308
    doc 14
      freq 2
      pos 5720
      pos 5774
    doc 15
      freq 8
      pos 684
      pos 1332
      pos 1510
      pos 1530
      pos 2665
      pos 3550
      pos 4239
      pos 4293
    doc 16
      freq 2
      pos 2850
      pos 2904
    doc 17
      freq 2
      pos 2574
      pos 2628
    doc 18
      freq 2
      pos 2362
      pos 2416
    skipList 
      level 0
        skipDoc 7
        skipDocFP 454625
        impacts 
          impact 
            freq 2
            norm 100
          impact 
            freq 4
            norm 101
          impact 
            freq 6
            norm 104
        impactsEnd 
        skipDoc 15
        skipDocFP 455215
        impacts 
          impact 
            freq 2
            norm 95
          impact 
            freq 8
            norm 104
          impact 
            freq 12
            norm 109
        impactsEnd 
  term avaya
    doc 11
      freq 2
      pos 20
      pos 10556
  term ave
    doc 1
      freq 1
      pos 9373
    doc 3
      freq 2
      pos 4863
      pos 4876
  term avenu
    doc 1
      freq 3
      pos 9387
      pos 9513
      pos 9565
    doc 3
      freq 3
      pos 4773
      pos 5878
      pos 5930
    doc 4
      freq 1
      pos 6081
    doc 8
      freq 1
      pos 2137
    doc 11
      freq 1
      pos 8442
    doc 13
      freq 1
      pos 7067
    doc 15
      freq 1
      pos 1729
  term averag
    doc 4
      freq 2
      pos 1899
      pos 1939
    doc 6
      freq 1
      pos 2383
  term aviv
    doc 3
      freq 1
      pos 4924
  term avoid
    doc 0
      freq 3
      pos 2920
      pos 16233
      pos 16517
    doc 1
      freq 1
      pos 7606
    doc 2
      freq 2
      pos 4416
      pos 5588
    doc 7
      freq 1
      pos 1245
    doc 9
      freq 1
      pos 1043
    doc 11
      freq 1
      pos 743
    doc 12
      freq 6
      pos 617
      pos 1089
      pos 2094
      pos 2992
      pos 5244
      pos 5404
    doc 13
      freq 4
      pos 5757
      pos 6288
      pos 6422
      pos 6445
    doc 17
      freq 1
      pos 1489
    skipList 
      level 0
        skipDoc 13
        skipDocFP 457385
        impacts 
          impact 
            freq 1
            norm 95
          impact 
            freq 2
            norm 108
          impact 
            freq 4
            norm 109
          impact 
            freq 6
            norm 113
        impactsEnd 
  term avoidanc
    doc 3
      freq 1
      pos 3296
  term avoided
    doc 4
      freq 1
      pos 4519
    doc 8
      freq 1
      pos 411
    doc 14
      freq 1
      pos 2266
    doc 17
      freq 1
      pos 1767
  term avoiding
    doc 12
      freq 3
      pos 169
      pos 1082
      pos 6738
    doc 14
      freq 1
      pos 289
    doc 17
      freq 1
      pos 1572
  term avoids
    doc 14
      freq 1
      pos 2228
  term avp
    doc 10
      freq 3
      pos 6398
      pos 6535
      pos 6698
    doc 11
      freq 39
      pos 1553
      pos 1560
      pos 2271
      pos 2278
      pos 3189
      pos 3196
      pos 3422
      pos 3429
      pos 4065
      pos 4072
      pos 4330
      pos 4337
      pos 4511
      pos 4518
      pos 4725
      pos 4732
      pos 5216
      pos 5223
      pos 5373
      pos 5380
      pos 5521
      pos 5528
      pos 5681
      pos 5688
      pos 6001
      pos 6008
      pos 6225
      pos 6232
      pos 6911
      pos 6918
      pos 7249
      pos 7256
      pos 8205
      pos 8212
      pos 8534
      pos 8541
      pos 9129
      pos 9136
      pos 9306
  term aware
    doc 0
      freq 3
      pos 3618
      pos 4134
      pos 10975
    doc 2
      freq 1
      pos 5404
    doc 3
      freq 1
      pos 3576
    doc 8
      freq 1
      pos 2023
    doc 13
      freq 2
      pos 5288
      pos 5365
    doc 14
      freq 1
      pos 99
    doc 15
      freq 1
      pos 3514
  term away
    doc 12
      freq 1
      pos 3830
    doc 15
      freq 1
      pos 2540
  term awxvegkxdtalbgnvbaombelfveyxgzazbgnvbammemjpbg94as5legftcgxllmnv
    doc 10
      freq 1
      pos 6884
  term axiowav
    doc 0
      freq 1
      pos 10
  term aypni
    doc 11
      freq 1
      pos 10409
  term azkh8kdbyyjj7bhwrexgjmwxigfqrxpyx
    doc 10
      freq 1
      pos 12490
  term b
    doc 0
      freq 3
      pos 17020
      pos 17112
      pos 17180
    doc 1
      freq 1
      pos 8921
    doc 2
      freq 13
      pos 3
      pos 181
      pos 2327
      pos 2339
      pos 2796
      pos 3050
      pos 3105
      pos 3120
      pos 3137
      pos 3162
      pos 3265
      pos 3289
      pos 6339
    doc 3
      freq 12
      pos 306
      pos 310
      pos 320
      pos 906
      pos 926
      pos 1091
      pos 4034
      pos 4619
      pos 5049
      pos 5426
      pos 5596
      pos 5797
    doc 4
      freq 5
      pos 959
      pos 1136
      pos 1415
      pos 1924
      pos 2030
    doc 5
      freq 2
      pos 1002
      pos 4192
    doc 6
      freq 2
      pos 2221
      pos 2229
    doc 8
      freq 1
      pos 2084
    doc 10
      freq 6
      pos 362
      pos 371
      pos 6180
      pos 12156
      pos 12177
      pos 12445
    doc 11
      freq 3
      pos 10064
      pos 10261
      pos 10440
    doc 12
      freq 18
      pos 457
      pos 467
      pos 475
      pos 485
      pos 743
      pos 2893
      pos 7111
      pos 7143
      pos 7177
      pos 7202
      pos 7318
      pos 7412
      pos 7864
      pos 8074
      pos 8112
      pos 8341
      pos 8642
      pos 9054
    doc 13
      freq 1
      pos 6922
    doc 14
      freq 1
      pos 9
    doc 15
      freq 2
      pos 3943
      pos 3982
    skipList 
      level 0
        skipDoc 8
        skipDocFP 460083
        impacts 
          impact 
            freq 1
            norm 97
          impact 
            freq 2
            norm 101
          impact 
            freq 12
            norm 107
          impact 
            freq 13
            norm 108
        impactsEnd 
  term b.d
    doc 12
      freq 1
      pos 5347
  term b0f0bgfudgexdtalbgnvbaombelfveyxhdaabgnvbamme2f0bgfudgeuzxhhbxbs
    doc 10
      freq 1
      pos 6252
  term b0qxqp8lt
    doc 11
      freq 1
      pos 9935
  term b2
    doc 10
      freq 1
      pos 12462
  term b2ku878p1ifsxf
    doc 11
      freq 1
      pos 10394
  term b2t5l664qm6w7rtuyycy8pwpxawcenwfjm42p
    doc 11
      freq 1
      pos 10489
  term b37f7cdm
    doc 10
      freq 1
      pos 12645
  term b3euc3eeh6ieptuyl1zfrcpr22rpxujfs9epx0s
    doc 10
      freq 1
      pos 12491
  term b3w
    doc 11
      freq 1
      pos 9923
  term b4a
    doc 10
      freq 1
      pos 12746
  term b4f
    doc 11
      freq 1
      pos 9879
  term b6aa3abb3e66cccb5dd6c64b8383149c
    doc 11
      freq 1
      pos 3911
  term b8e6ff182d944fe57b65bc99d005
    doc 11
      freq 1
      pos 3912
  term b8egdxoenj3m1i51wycsm035
    doc 10
      freq 1
      pos 12627
  term b9nf
    doc 11
      freq 1
      pos 10280
  term back
    doc 0
      freq 2
      pos 7057
      pos 7059
    doc 3
      freq 1
      pos 1589
    doc 4
      freq 4
      pos 2553
      pos 4365
      pos 4367
      pos 5656
    doc 10
      freq 2
      pos 4086
      pos 10645
    doc 11
      freq 1
      pos 7089
    doc 12
      freq 4
      pos 2913
      pos 2919
      pos 3645
      pos 3750
    doc 16
      freq 3
      pos 158
      pos 222
      pos 1771
  term backbon
    doc 1
      freq 1
      pos 124
    doc 13
      freq 1
      pos 2717
  term backes
    doc 2
      freq 1
      pos 3607
  term background
    doc 3
      freq 1
      pos 5701
    doc 9
      freq 1
      pos 1757
    doc 10
      freq 2
      pos 188
      pos 712
    doc 12
      freq 2
      pos 798
      pos 2885
    doc 13
      freq 2
      pos 139
      pos 365
  term backslash
    doc 14
      freq 1
      pos 2944
  term backup
    doc 17
      freq 2
      pos 1556
      pos 1565
  term backus
    doc 16
      freq 1
      pos 1419
  term backward
    doc 11
      freq 2
      pos 521
      pos 9143
    doc 18
      freq 1
      pos 1219
  term backwards
    doc 3
      freq 1
      pos 3551
    doc 10
      freq 7
      pos 3492
      pos 3558
      pos 3581
      pos 3603
      pos 3690
      pos 3735
      pos 4609
    doc 11
      freq 1
      pos 9175
  term bad
    doc 0
      freq 1
      pos 7336
    doc 10
      freq 5
      pos 324
      pos 4058
      pos 11104
      pos 11638
      pos 11728
    doc 11
      freq 17
      pos 4265
      pos 4385
      pos 4801
      pos 5108
      pos 5275
      pos 5426
      pos 5872
      pos 6310
      pos 6419
      pos 6531
      pos 6758
      pos 6835
      pos 7201
      pos 7613
      pos 7700
      pos 8116
      pos 9045
    doc 12
      freq 1
      pos 1007
    doc 16
      freq 2
      pos 622
      pos 1272
  term badaspec
    doc 11
      freq 1
      pos 6433
  term badaspec.sdf0234n2nds0a099u23h3hnnw009cdkne3
    doc 11
      freq 1
      pos 6465
  term badbranch
    doc 11
      freq 1
      pos 7099
  term badbranch.sadonfo23i420jv0as0derf3j3n
    doc 11
      freq 1
      pos 7128
  term baddat
    doc 11
      freq 2
      pos 6152
      pos 6171
  term baddn
    doc 11
      freq 2
      pos 6595
      pos 6626
  term badinv01
    doc 11
      freq 1
      pos 4270
  term badinv01.0ha0isndaksdjasdf3234nas
    doc 11
      freq 1
      pos 4289
  term badurl
    doc 16
      freq 11
      pos 594
      pos 1248
      pos 1251
      pos 1286
      pos 1503
      pos 1510
      pos 1513
      pos 1552
      pos 2271
      pos 2455
      pos 2493
  term badvers
    doc 11
      freq 2
      pos 6672
      pos 6702
  term baker
    doc 0
      freq 1
      pos 16995
    doc 2
      freq 3
      pos 2255
      pos 3468
      pos 3566
    doc 12
      freq 2
      pos 7387
      pos 7528
  term balanc
    doc 6
      freq 3
      pos 1282
      pos 1559
      pos 1571
  term balanced
    doc 11
      freq 1
      pos 1826
  term balancers
    doc 12
      freq 5
      pos 223
      pos 1628
      pos 1672
      pos 1685
      pos 3499
  term balancing
    doc 3
      freq 1
      pos 3303
    doc 15
      freq 5
      pos 232
      pos 1284
      pos 1304
      pos 1329
      pos 2014
  term balay
    doc 0
      freq 1
      pos 17132
  term ballot
    doc 2
      freq 8
      pos 1812
      pos 1832
      pos 1837
      pos 5384
      pos 5457
      pos 5540
      pos 5572
      pos 6263
  term balloting
    doc 2
      freq 1
      pos 4525
  term ballots
    doc 2
      freq 2
      pos 5408
      pos 5435
  term band
    doc 5
      freq 3
      pos 191
      pos 2202
      pos 2498
    doc 13
      freq 1
      pos 2421
    doc 17
      freq 1
      pos 1923
  term bands
    doc 2
      freq 1
      pos 2743
  term bandwidth
    doc 4
      freq 3
      pos 1827
      pos 1919
      pos 5588
    doc 6
      freq 2
      pos 366
      pos 2798
    doc 13
      freq 9
      pos 945
      pos 1310
      pos 2102
      pos 2400
      pos 2580
      pos 2725
      pos 3445
      pos 4365
      pos 5038
    doc 16
      freq 1
      pos 357
  term banyan
    doc 7
      freq 2
      pos 1081
      pos 2674
  term bar
    doc 16
      freq 3
      pos 1951
      pos 1993
      pos 2376
  term bar.foo.example.com
    doc 14
      freq 2
      pos 4985
      pos 5158
  term barber
    doc 12
      freq 1
      pos 7748
  term bari
    doc 2
      freq 1
      pos 2305
  term bars
    doc 10
      freq 1
      pos 7204
  term bartlett
    doc 0
      freq 1
      pos 15912
  term base
    doc 0
      freq 6
      pos 19
      pos 98
      pos 235
      pos 307
      pos 1128
      pos 17004
    doc 1
      freq 1
      pos 2234
    doc 3
      freq 2
      pos 4545
      pos 4603
    doc 4
      freq 1
      pos 510
    doc 6
      freq 1
      pos 484
    doc 7
      freq 9
      pos 723
      pos 971
      pos 1042
      pos 1051
      pos 2060
      pos 2423
      pos 2551
      pos 2587
      pos 2628
    doc 10
      freq 2
      pos 12421
      pos 12441
    doc 11
      freq 2
      pos 9828
      pos 9848
    doc 13
      freq 1
      pos 2105
    doc 16
      freq 3
      pos 901
      pos 952
      pos 1615
    skipList 
      level 0
        skipDoc 11
        skipDocFP 467364
        impacts 
          impact 
            freq 9
            norm 100
        impactsEnd 
  term base16
    doc 10
      freq 1
      pos 13216
  term base32
    doc 10
      freq 1
      pos 13217
  term base64
    doc 10
      freq 9
      pos 5525
      pos 5987
      pos 6554
      pos 6577
      pos 7259
      pos 7295
      pos 12261
      pos 12400
      pos 13219
    doc 11
      freq 1
      pos 9805
  term basecertificateid
    doc 17
      freq 2
      pos 1701
      pos 1724
  term based
    doc 0
      freq 3
      pos 1159
      pos 9270
      pos 15842
    doc 1
      freq 1
      pos 1551
    doc 2
      freq 10
      pos 1933
      pos 2490
      pos 2511
      pos 3896
      pos 4132
      pos 4244
      pos 4448
      pos 5293
      pos 5297
      pos 5306
    doc 3
      freq 9
      pos 1281
      pos 1302
      pos 3272
      pos 4049
      pos 5034
      pos 5461
      pos 5505
      pos 5668
      pos 5836
    doc 4
      freq 4
      pos 1962
      pos 5585
      pos 5589
      pos 5604
    doc 5
      freq 6
      pos 126
      pos 413
      pos 487
      pos 730
      pos 1447
      pos 2151
    doc 6
      freq 5
      pos 123
      pos 423
      pos 1431
      pos 1662
      pos 1670
    doc 7
      freq 9
      pos 409
      pos 638
      pos 662
      pos 676
      pos 820
      pos 1536
      pos 1543
      pos 1726
      pos 2230
    doc 10
      freq 9
      pos 1554
      pos 3874
      pos 4529
      pos 8957
      pos 9672
      pos 10040
      pos 10720
      pos 11151
      pos 11162
    doc 11
      freq 3
      pos 578
      pos 783
      pos 4395
    doc 12
      freq 14
      pos 952
      pos 1591
      pos 4452
      pos 4755
      pos 5493
      pos 5538
      pos 5570
      pos 5838
      pos 6098
      pos 6126
      pos 6140
      pos 6420
      pos 6468
      pos 6868
    doc 13
      freq 20
      pos 168
      pos 373
      pos 541
      pos 729
      pos 745
      pos 1720
      pos 1960
      pos 2008
      pos 2025
      pos 2113
      pos 2257
      pos 2290
      pos 2501
      pos 2627
      pos 2811
      pos 2820
      pos 2979
      pos 3875
      pos 3897
      pos 4627
    doc 15
      freq 2
      pos 1574
      pos 2209
    skipList 
      level 0
        skipDoc 7
        skipDocFP 468591
        impacts 
          impact 
            freq 9
            norm 100
          impact 
            freq 10
            norm 108
        impactsEnd 
  term baselin
    doc 10
      freq 1
      pos 7105
  term bases
    doc 2
      freq 1
      pos 224
  term basic
    doc 0
      freq 1
      pos 2215
    doc 2
      freq 1
      pos 4541
    doc 8
      freq 1
      pos 767
    doc 12
      freq 1
      pos 7577
    doc 13
      freq 1
      pos 6699
  term basically
    doc 12
      freq 2
      pos 2303
      pos 3282
  term basis
    doc 0
      freq 1
      pos 17271
    doc 1
      freq 1
      pos 9652
    doc 2
      freq 3
      pos 1870
      pos 4069
      pos 6449
    doc 3
      freq 2
      pos 1656
      pos 6001
    doc 4
      freq 2
      pos 2709
      pos 6156
    doc 5
      freq 1
      pos 4486
    doc 6
      freq 1
      pos 3286
    doc 7
      freq 2
      pos 1669
      pos 2991
    doc 8
      freq 2
      pos 270
      pos 2208
    doc 9
      freq 2
      pos 605
      pos 1853
    doc 10
      freq 2
      pos 11397
      pos 13514
    doc 11
      freq 1
      pos 10675
    doc 12
      freq 1
      pos 9525
    doc 13
      freq 2
      pos 555
      pos 7140
    doc 14
      freq 1
      pos 5606
    doc 15
      freq 2
      pos 3175
      pos 4125
    doc 16
      freq 1
      pos 2736
    doc 17
      freq 2
      pos 140
      pos 2460
    doc 18
      freq 1
      pos 2248
    skipList 
      level 0
        skipDoc 7
        skipDocFP 470926
        impacts 
          impact 
            freq 2
            norm 100
          impact 
            freq 3
            norm 108
        impactsEnd 
        skipDoc 15
        skipDocFP 471306
        impacts 
          impact 
            freq 2
            norm 95
        impactsEnd 
  term battery
    doc 13
      freq 3
      pos 2075
      pos 2124
      pos 4165
  term baugher
    doc 5
      freq 3
      pos 4072
      pos 4211
      pos 4354
  term bauwaweb
    doc 10
      freq 1
      pos 6906
  term bavar
    doc 5
      freq 2
      pos 4406
      pos 4420
  term bbbr
    doc 10
      freq 1
      pos 12807
  term bc1erlxbsvgmhxavic3h4c8
    doc 10
      freq 1
      pos 12660
  term bc6fouub
    doc 10
      freq 1
      pos 12473
  term bcast
    doc 11
      freq 2
      pos 8466
      pos 8487
  term bcncp
    doc 10
      freq 1
      pos 12816
  term bcp
    doc 0
      freq 5
      pos 983
      pos 16954
      pos 17244
      pos 17417
      pos 17420
    doc 1
      freq 5
      pos 8965
      pos 9175
      pos 9625
      pos 9798
      pos 9801
    doc 2
      freq 6
      pos 2242
      pos 2266
      pos 3363
      pos 6422
      pos 6595
      pos 6598
    doc 3
      freq 5
      pos 4348
      pos 4505
      pos 5974
      pos 6147
      pos 6150
    doc 4
      freq 6
      pos 5280
      pos 5294
      pos 5322
      pos 6129
      pos 6302
      pos 6305
    doc 5
      freq 5
      pos 4135
      pos 4156
      pos 4459
      pos 4632
      pos 4635
    doc 6
      freq 3
      pos 3254
      pos 3432
      pos 3435
    doc 7
      freq 4
      pos 1812
      pos 2964
      pos 3137
      pos 3140
    doc 8
      freq 7
      pos 12
      pos 1740
      pos 1756
      pos 1775
      pos 2181
      pos 2354
      pos 2357
    doc 9
      freq 6
      pos 1678
      pos 1697
      pos 1714
      pos 1826
      pos 1999
      pos 2002
    doc 10
      freq 4
      pos 13129
      pos 13487
      pos 13660
      pos 13663
    doc 11
      freq 3
      pos 10648
      pos 10821
      pos 10824
    doc 12
      freq 7
      pos 7066
      pos 7165
      pos 7339
      pos 7538
      pos 9498
      pos 9671
      pos 9674
    doc 13
      freq 4
      pos 6748
      pos 7113
      pos 7286
      pos 7289
    doc 14
      freq 3
      pos 5579
      pos 5752
      pos 5755
    doc 15
      freq 3
      pos 4098
      pos 4271
      pos 4274
    doc 16
      freq 3
      pos 2709
      pos 2882
      pos 2885
    doc 17
      freq 4
      pos 2040
      pos 2433
      pos 2606
      pos 2609
    doc 18
      freq 4
      pos 2139
      pos 2221
      pos 2394
      pos 2397
    skipList 
      level 0
        skipDoc 7
        skipDocFP 472782
        impacts 
          impact 
            freq 4
            norm 100
          impact 
            freq 5
            norm 104
          impact 
            freq 6
            norm 108
        impactsEnd 
        skipDoc 15
        skipDocFP 473554
        impacts 
          impact 
            freq 6
            norm 95
          impact 
            freq 7
            norm 97
        impactsEnd 
  term bcp102
    doc 2
      freq 2
      pos 528
      pos 2227
  term bcp103
    doc 2
      freq 2
      pos 539
      pos 2248
  term bdata
    doc 10
      freq 4
      pos 12397
      pos 12414
      pos 12415
      pos 12418
    doc 11
      freq 4
      pos 9802
      pos 9819
      pos 9820
      pos 9823
  term be
    doc 0
      freq 114
      pos 559
      pos 748
      pos 942
      pos 978
      pos 1446
      pos 1558
      pos 2204
      pos 2207
      pos 2232
      pos 2353
      pos 2446
      pos 2496
      pos 2573
      pos 2583
      pos 2627
      pos 2830
      pos 2879
      pos 3069
      pos 3206
      pos 3302
      pos 3578
      pos 3617
      pos 3653
      pos 3813
      pos 3851
      pos 3869
      pos 3909
      pos 3989
      pos 4035
      pos 4058
      pos 4133
      pos 4169
      pos 4313
      pos 4351
      pos 4369
      pos 4421
      pos 4783
      pos 4986
      pos 5002
      pos 5338
      pos 5387
      pos 5540
      pos 5546
      pos 5569
      pos 5615
      pos 5705
      pos 5754
      pos 5841
      pos 5852
      pos 5859
      pos 5999
      pos 6051
      pos 6102
      pos 6117
      pos 6124
      pos 6225
      pos 6247
      pos 6557
      pos 6573
      pos 6692
      pos 6815
      pos 9198
      pos 9207
      pos 10090
      pos 10140
      pos 10255
      pos 10264
      pos 10320
      pos 10342
      pos 10359
      pos 10556
      pos 10600
      pos 10645
      pos 10777
      pos 10974
      pos 11011
      pos 11177
      pos 11215
      pos 11233
      pos 11439
      pos 11612
      pos 12623
      pos 12768
      pos 12983
      pos 13041
      pos 14100
      pos 14122
      pos 14129
      pos 14410
      pos 14576
      pos 14793
      pos 14797
      pos 15853
      pos 15986
      pos 15998
      pos 16042
      pos 16060
      pos 16118
      pos 16172
      pos 16189
      pos 16202
      pos 16280
      pos 16300
      pos 16333
      pos 16495
      pos 16550
      pos 16621
      pos 16714
      pos 17354
      pos 17384
      pos 17414
      pos 17437
      pos 17469
      pos 17509
    doc 1
      freq 131
      pos 119
      pos 475
      pos 553
      pos 875
      pos 902
      pos 910
      pos 929
      pos 1120
      pos 1137
      pos 1180
      pos 1237
      pos 1294
      pos 1339
      pos 1351
      pos 1418
      pos 1435
      pos 1588
      pos 1620
      pos 1646
      pos 1669
      pos 1687
      pos 1703
      pos 1714
      pos 1735
      pos 1749
      pos 1761
      pos 1834
      pos 1843
      pos 1856
      pos 1885
      pos 1944
      pos 2006
      pos 2125
      pos 2149
      pos 2171
      pos 2264
      pos 2284
      pos 2396
      pos 2655
      pos 2676
      pos 2757
      pos 2822
      pos 2844
      pos 2902
      pos 2936
      pos 2968
      pos 3071
      pos 3160
      pos 3178
      pos 3200
      pos 3224
      pos 3270
      pos 3298
      pos 3391
      pos 3408
      pos 3436
      pos 3448
      pos 3721
      pos 3773
      pos 3952
      pos 3970
      pos 4060
      pos 4150
      pos 4225
      pos 4272
      pos 4477
      pos 4494
      pos 4515
      pos 4684
      pos 4741
      pos 4844
      pos 4875
      pos 4903
      pos 5007
      pos 5149
      pos 5164
      pos 5466
      pos 5493
      pos 5666
      pos 5852
      pos 5901
      pos 5981
      pos 6132
      pos 6165
      pos 6211
      pos 6263
      pos 6273
      pos 6339
      pos 6355
      pos 6411
      pos 6435
      pos 6452
      pos 6494
      pos 6991
      pos 7012
      pos 7038
      pos 7121
      pos 7149
      pos 7319
      pos 7413
      pos 7429
      pos 7523
      pos 7553
      pos 7958
      pos 8005
      pos 8048
      pos 8077
      pos 8091
      pos 8196
      pos 8262
      pos 8311
      pos 8353
      pos 8483
      pos 8493
      pos 8507
      pos 8528
      pos 8558
      pos 8589
      pos 8637
      pos 8648
      pos 8768
      pos 8778
      pos 8808
      pos 8819
      pos 8834
      pos 9735
      pos 9765
      pos 9795
      pos 9818
      pos 9850
      pos 9890
    doc 2
      freq 32
      pos 585
      pos 605
      pos 663
      pos 894
      pos 1154
      pos 1249
      pos 1360
      pos 1508
      pos 1513
      pos 1577
      pos 1709
      pos 1824
      pos 1878
      pos 2000
      pos 2006
      pos 2049
      pos 4157
      pos 4388
      pos 5078
      pos 5402
      pos 5561
      pos 5581
      pos 5892
      pos 6117
      pos 6273
      pos 6324
      pos 6532
      pos 6562
      pos 6592
      pos 6615
      pos 6647
      pos 6687
    doc 3
      freq 73
      pos 356
      pos 776
      pos 793
      pos 1024
      pos 1225
      pos 1255
      pos 1454
      pos 1463
      pos 1485
      pos 1522
      pos 1571
      pos 1601
      pos 1634
      pos 1667
      pos 1702
      pos 1718
      pos 1751
      pos 1850
      pos 1910
      pos 1950
      pos 2032
      pos 2098
      pos 2320
      pos 2393
      pos 2521
      pos 2629
      pos 2649
      pos 2783
      pos 2844
      pos 2905
      pos 2956
      pos 2993
      pos 3016
      pos 3030
      pos 3054
      pos 3068
      pos 3090
      pos 3118
      pos 3184
      pos 3408
      pos 3482
      pos 3494
      pos 3508
      pos 3556
      pos 3575
      pos 3593
      pos 3683
      pos 3705
      pos 3713
      pos 3727
      pos 3806
      pos 3912
      pos 3924
      pos 4057
      pos 4105
      pos 4119
      pos 4182
      pos 4226
      pos 4243
      pos 4283
      pos 4288
      pos 5069
      pos 5089
      pos 5165
      pos 5182
      pos 5564
      pos 5659
      pos 6084
      pos 6114
      pos 6144
      pos 6167
      pos 6199
      pos 6239
    doc 4
      freq 74
      pos 464
      pos 522
      pos 858
      pos 941
      pos 1132
      pos 1183
      pos 1194
      pos 1202
      pos 1227
      pos 1391
      pos 1409
      pos 1428
      pos 1637
      pos 1815
      pos 1908
      pos 1928
      pos 1985
      pos 2006
      pos 2029
      pos 2214
      pos 2232
      pos 2253
      pos 2269
      pos 2429
      pos 2451
      pos 2551
      pos 2702
      pos 2747
      pos 2862
      pos 2981
      pos 2993
      pos 3101
      pos 3217
      pos 3229
      pos 3532
      pos 3617
      pos 3650
      pos 3706
      pos 3882
      pos 3898
      pos 3925
      pos 3951
      pos 3969
      pos 3985
      pos 4010
      pos 4034
      pos 4059
      pos 4102
      pos 4111
      pos 4134
      pos 4164
      pos 4182
      pos 4215
      pos 4310
      pos 4325
      pos 4355
      pos 4384
      pos 4486
      pos 4518
      pos 4529
      pos 4899
      pos 4958
      pos 5040
      pos 5577
      pos 5760
      pos 5798
      pos 5975
      pos 6023
      pos 6239
      pos 6269
      pos 6299
      pos 6322
      pos 6354
      pos 6394
    doc 5
      freq 62
      pos 218
      pos 434
      pos 532
      pos 539
      pos 608
      pos 647
      pos 719
      pos 855
      pos 867
      pos 888
      pos 901
      pos 916
      pos 989
      pos 1033
      pos 1068
      pos 1091
      pos 1103
      pos 1136
      pos 1187
      pos 1388
      pos 1402
      pos 1421
      pos 1495
      pos 1650
      pos 1698
      pos 1790
      pos 1878
      pos 1899
      pos 1988
      pos 2056
      pos 2073
      pos 2289
      pos 2317
      pos 2485
      pos 2532
      pos 2594
      pos 2909
      pos 2949
      pos 2970
      pos 3075
      pos 3136
      pos 3199
      pos 3226
      pos 3251
      pos 3374
      pos 3430
      pos 3471
      pos 3495
      pos 3505
      pos 3547
      pos 3565
      pos 3585
      pos 3607
      pos 3630
      pos 3856
      pos 3885
      pos 4569
      pos 4599
      pos 4629
      pos 4652
      pos 4684
      pos 4724
    doc 6
      freq 43
      pos 187
      pos 256
      pos 498
      pos 533
      pos 578
      pos 605
      pos 640
      pos 677
      pos 725
      pos 810
      pos 988
      pos 1029
      pos 1116
      pos 1284
      pos 1291
      pos 1309
      pos 1398
      pos 1417
      pos 1460
      pos 1475
      pos 1492
      pos 1503
      pos 1531
      pos 2072
      pos 2387
      pos 2391
      pos 2444
      pos 2492
      pos 2508
      pos 2552
      pos 2577
      pos 2622
      pos 2637
      pos 2671
      pos 2740
      pos 2850
      pos 2863
      pos 3369
      pos 3399
      pos 3429
      pos 3452
      pos 3484
      pos 3524
    doc 7
      freq 25
      pos 188
      pos 245
      pos 326
      pos 352
      pos 372
      pos 380
      pos 430
      pos 496
      pos 601
      pos 1234
      pos 1254
      pos 1311
      pos 1317
      pos 1361
      pos 1397
      pos 1602
      pos 1631
      pos 1642
      pos 1759
      pos 3074
      pos 3104
      pos 3134
      pos 3157
      pos 3189
      pos 3229
    doc 8
      freq 36
      pos 216
      pos 237
      pos 248
      pos 262
      pos 285
      pos 328
      pos 374
      pos 410
      pos 423
      pos 430
      pos 520
      pos 542
      pos 567
      pos 616
      pos 850
      pos 872
      pos 898
      pos 934
      pos 994
      pos 1176
      pos 1198
      pos 1223
      pos 1259
      pos 1288
      pos 1357
      pos 1379
      pos 1404
      pos 1454
      pos 1483
      pos 1546
      pos 2291
      pos 2321
      pos 2351
      pos 2374
      pos 2406
      pos 2446
    doc 9
      freq 34
      pos 108
      pos 270
      pos 327
      pos 365
      pos 430
      pos 460
      pos 535
      pos 697
      pos 755
      pos 778
      pos 807
      pos 861
      pos 949
      pos 964
      pos 972
      pos 983
      pos 1001
      pos 1039
      pos 1072
      pos 1090
      pos 1138
      pos 1191
      pos 1222
      pos 1244
      pos 1443
      pos 1471
      pos 1506
      pos 1591
      pos 1936
      pos 1966
      pos 1996
      pos 2019
      pos 2051
      pos 2091
    doc 10
      freq 128
      pos 521
      pos 592
      pos 695
      pos 729
      pos 734
      pos 745
      pos 773
      pos 840
      pos 875
      pos 920
      pos 968
      pos 1133
      pos 1339
      pos 1423
      pos 1659
      pos 1710
      pos 1726
      pos 1883
      pos 1889
      pos 2074
      pos 2116
      pos 2149
      pos 2168
      pos 2215
      pos 2368
      pos 2569
      pos 2662
      pos 2684
      pos 2759
      pos 2867
      pos 2916
      pos 3073
      pos 3167
      pos 3351
      pos 3570
      pos 3609
      pos 3895
      pos 3986
      pos 4053
      pos 4063
      pos 4109
      pos 4122
      pos 4242
      pos 4317
      pos 4339
      pos 4369
      pos 4379
      pos 4522
      pos 4536
      pos 4612
      pos 4888
      pos 5025
      pos 5030
      pos 5129
      pos 5137
      pos 5185
      pos 5190
      pos 5272
      pos 5279
      pos 5349
      pos 5362
      pos 5376
      pos 5413
      pos 5464
      pos 5505
      pos 5543
      pos 5630
      pos 5862
      pos 5878
      pos 6464
      pos 7214
      pos 7667
      pos 7841
      pos 7905
      pos 8016
      pos 8247
      pos 8273
      pos 8670
      pos 8700
      pos 8773
      pos 8881
      pos 8930
      pos 9021
      pos 9033
      pos 9316
      pos 9528
      pos 9695
      pos 9737
      pos 9792
      pos 9833
      pos 10236
      pos 10266
      pos 10420
      pos 10490
      pos 10516
      pos 10545
      pos 10688
      pos 10832
      pos 10866
      pos 10967
      pos 11121
      pos 11174
      pos 11300
      pos 11360
      pos 11379
      pos 11390
      pos 11592
      pos 11670
      pos 11945
      pos 11997
      pos 12027
      pos 12081
      pos 12357
      pos 12369
      pos 12426
      pos 12886
      pos 12902
      pos 12925
      pos 12946
      pos 12971
      pos 13003
      pos 13029
      pos 13597
      pos 13627
      pos 13657
      pos 13680
      pos 13712
      pos 13752
    doc 11
      freq 51
      pos 683
      pos 790
      pos 919
      pos 1106
      pos 1131
      pos 1148
      pos 1176
      pos 1293
      pos 1393
      pos 1803
      pos 1914
      pos 1958
      pos 2656
      pos 3266
      pos 4113
      pos 4199
      pos 4210
      pos 4560
      pos 4580
      pos 4638
      pos 5280
      pos 5879
      pos 5915
      pos 6087
      pos 6282
      pos 6293
      pos 6316
      pos 6339
      pos 6425
      pos 6539
      pos 6585
      pos 6591
      pos 8290
      pos 8310
      pos 8367
      pos 8666
      pos 9025
      pos 9165
      pos 9223
      pos 9385
      pos 9389
      pos 9405
      pos 9774
      pos 9786
      pos 9833
      pos 10758
      pos 10788
      pos 10818
      pos 10841
      pos 10873
      pos 10913
    doc 12
      freq 137
      pos 523
      pos 571
      pos 895
      pos 925
      pos 973
      pos 1072
      pos 1213
      pos 1300
      pos 1377
      pos 1426
      pos 1465
      pos 1480
      pos 1611
      pos 1663
      pos 1852
      pos 1891
      pos 1977
      pos 2105
      pos 2219
      pos 2300
      pos 2320
      pos 2369
      pos 2385
      pos 2532
      pos 2599
      pos 2772
      pos 2784
      pos 2964
      pos 2967
      pos 2998
      pos 3051
      pos 3090
      pos 3177
      pos 3206
      pos 3366
      pos 3525
      pos 3563
      pos 3679
      pos 3711
      pos 3795
      pos 3843
      pos 3893
      pos 3897
      pos 3936
      pos 3943
      pos 3995
      pos 4106
      pos 4152
      pos 4159
      pos 4237
      pos 4268
      pos 4382
      pos 4471
      pos 4477
      pos 4491
      pos 4516
      pos 4537
      pos 4547
      pos 4650
      pos 4662
      pos 4691
      pos 4721
      pos 4729
      pos 4744
      pos 4779
      pos 4838
      pos 4855
      pos 4911
      pos 4930
      pos 5153
      pos 5191
      pos 5237
      pos 5269
      pos 5294
      pos 5360
      pos 5385
      pos 5520
      pos 5612
      pos 5667
      pos 5686
      pos 5778
      pos 5844
      pos 5916
      pos 5937
      pos 5990
      pos 6062
      pos 6095
      pos 6123
      pos 6151
      pos 6275
      pos 6358
      pos 6374
      pos 6392
      pos 6423
      pos 6433
      pos 6460
      pos 6472
      pos 6486
      pos 6616
      pos 6648
      pos 6657
      pos 6879
      pos 6884
      pos 6902
      pos 6927
      pos 6968
      pos 7997
      pos 8038
      pos 8132
      pos 8148
      pos 8163
      pos 8297
      pos 8364
      pos 8442
      pos 8458
      pos 8474
      pos 8492
      pos 8504
      pos 8548
      pos 8714
      pos 8783
      pos 8790
      pos 8909
      pos 8921
      pos 8958
      pos 9075
      pos 9134
      pos 9255
      pos 9263
      pos 9290
      pos 9303
      pos 9608
      pos 9638
      pos 9668
      pos 9691
      pos 9723
      pos 9763
    doc 13
      freq 130
      pos 576
      pos 673
      pos 696
      pos 737
      pos 772
      pos 801
      pos 813
      pos 840
      pos 859
      pos 878
      pos 904
      pos 936
      pos 956
      pos 981
      pos 1204
      pos 1254
      pos 1805
      pos 1837
      pos 1955
      pos 1987
      pos 2042
      pos 2197
      pos 2390
      pos 2439
      pos 2473
      pos 2513
      pos 2600
      pos 2630
      pos 2708
      pos 2735
      pos 2782
      pos 2858
      pos 2922
      pos 2967
      pos 2997
      pos 3010
      pos 3033
      pos 3044
      pos 3050
      pos 3086
      pos 3100
      pos 3131
      pos 3145
      pos 3158
      pos 3229
      pos 3250
      pos 3258
      pos 3340
      pos 3456
      pos 3492
      pos 3511
      pos 3593
      pos 3653
      pos 3716
      pos 3752
      pos 3886
      pos 3981
      pos 4052
      pos 4141
      pos 4148
      pos 4188
      pos 4207
      pos 4279
      pos 4341
      pos 4353
      pos 4434
      pos 4589
      pos 4630
      pos 4656
      pos 4683
      pos 4866
      pos 4876
      pos 4916
      pos 5136
      pos 5230
      pos 5281
      pos 5287
      pos 5364
      pos 5395
      pos 5443
      pos 5456
      pos 5491
      pos 5510
      pos 5527
      pos 5559
      pos 5584
      pos 5684
      pos 5754
      pos 5796
      pos 5810
      pos 5817
      pos 5834
      pos 5860
      pos 5874
      pos 5900
      pos 5926
      pos 5968
      pos 5983
      pos 6061
      pos 6083
      pos 6112
      pos 6144
      pos 6154
      pos 6170
      pos 6183
      pos 6203
      pos 6217
      pos 6238
      pos 6257
      pos 6270
      pos 6300
      pos 6345
      pos 6356
      pos 6412
      pos 6419
      pos 6442
      pos 6468
      pos 6504
      pos 6506
      pos 6523
      pos 6544
      pos 6552
      pos 6575
      pos 6636
      pos 7223
      pos 7253
      pos 7283
      pos 7306
      pos 7338
      pos 7378
    doc 14
      freq 36
      pos 89
      pos 355
      pos 376
      pos 551
      pos 677
      pos 1810
      pos 1940
      pos 2018
      pos 2033
      pos 2051
      pos 2092
      pos 2184
      pos 2235
      pos 2264
      pos 2275
      pos 2409
      pos 2485
      pos 2516
      pos 2544
      pos 2613
      pos 2644
      pos 2680
      pos 2711
      pos 2769
      pos 2857
      pos 2875
      pos 3559
      pos 4527
      pos 5301
      pos 5311
      pos 5689
      pos 5719
      pos 5749
      pos 5772
      pos 5804
      pos 5844
    doc 15
      freq 71
      pos 184
      pos 436
      pos 466
      pos 474
      pos 488
      pos 658
      pos 805
      pos 852
      pos 872
      pos 887
      pos 941
      pos 970
      pos 974
      pos 1116
      pos 1146
      pos 1236
      pos 1258
      pos 1263
      pos 1477
      pos 1548
      pos 1561
      pos 1620
      pos 1635
      pos 1640
      pos 1719
      pos 1843
      pos 1858
      pos 1970
      pos 2022
      pos 2047
      pos 2128
      pos 2134
      pos 2295
      pos 2300
      pos 2325
      pos 2348
      pos 2495
      pos 2505
      pos 2619
      pos 2686
      pos 2700
      pos 2711
      pos 2775
      pos 2906
      pos 3065
      pos 3071
      pos 3088
      pos 3097
      pos 3125
      pos 3135
      pos 3140
      pos 3195
      pos 3202
      pos 3249
      pos 3259
      pos 3264
      pos 3312
      pos 3321
      pos 3335
      pos 3351
      pos 3387
      pos 3439
      pos 3633
      pos 3654
      pos 3767
      pos 4208
      pos 4238
      pos 4268
      pos 4291
      pos 4323
      pos 4363
    doc 16
      freq 16
      pos 423
      pos 476
      pos 550
      pos 809
      pos 1214
      pos 1369
      pos 1430
      pos 1873
      pos 2131
      pos 2293
      pos 2819
      pos 2849
      pos 2879
      pos 2902
      pos 2934
      pos 2974
    doc 17
      freq 34
      pos 136
      pos 211
      pos 288
      pos 391
      pos 431
      pos 442
      pos 572
      pos 682
      pos 716
      pos 771
      pos 963
      pos 1177
      pos 1248
      pos 1255
      pos 1327
      pos 1335
      pos 1342
      pos 1357
      pos 1453
      pos 1461
      pos 1502
      pos 1508
      pos 1590
      pos 1647
      pos 1766
      pos 1779
      pos 1881
      pos 1884
      pos 2543
      pos 2573
      pos 2603
      pos 2626
      pos 2658
      pos 2698
    doc 18
      freq 25
      pos 345
      pos 403
      pos 421
      pos 564
      pos 587
      pos 610
      pos 706
      pos 853
      pos 924
      pos 942
      pos 1072
      pos 1083
      pos 1112
      pos 1126
      pos 1186
      pos 1225
      pos 1693
      pos 1778
      pos 1833
      pos 2331
      pos 2361
      pos 2391
      pos 2414
      pos 2446
      pos 2486
    skipList 
      level 0
        skipDoc 7
        skipDocFP 475345
        impacts 
          impact 
            freq 25
            norm 100
          impact 
            freq 43
            norm 101
          impact 
            freq 62
            norm 104
          impact 
            freq 73
            norm 107
          impact 
            freq 74
            norm 108
          impact 
            freq 131
            norm 113
        impactsEnd 
        skipDoc 15
        skipDocFP 483845
        impacts 
          impact 
            freq 34
            norm 95
          impact 
            freq 36
            norm 97
          impact 
            freq 71
            norm 104
          impact 
            freq 130
            norm 109
          impact 
            freq 137
            norm 113
        impactsEnd 
  term bear
    doc 18
      freq 1
      pos 447
  term becam
    doc 2
      freq 1
      pos 4792
  term becaus
    doc 0
      freq 3
      pos 10293
      pos 14101
      pos 14110
    doc 2
      freq 2
      pos 3528
      pos 4343
    doc 3
      freq 3
      pos 3359
      pos 5384
      pos 5392
    doc 4
      freq 2
      pos 2876
      pos 4542
    doc 10
      freq 12
      pos 3220
      pos 4342
      pos 4376
      pos 4389
      pos 5864
      pos 6475
      pos 7225
      pos 8561
      pos 8615
      pos 8638
      pos 10826
      pos 11770
    doc 11
      freq 2
      pos 5252
      pos 7189
    doc 12
      freq 10
      pos 991
      pos 1005
      pos 1178
      pos 1310
      pos 1586
      pos 1748
      pos 2958
      pos 4263
      pos 4932
      pos 5608
    doc 13
      freq 3
      pos 806
      pos 2677
      pos 5028
    doc 15
      freq 1
      pos 1238
    doc 16
      freq 2
      pos 342
      pos 880
    skipList 
      level 0
        skipDoc 13
        skipDocFP 495477
        impacts 
          impact 
            freq 3
            norm 107
          impact 
            freq 10
            norm 113
          impact 
            freq 12
            norm 116
        impactsEnd 
  term becom
    doc 0
      freq 3
      pos 7460
      pos 12943
      pos 16587
    doc 2
      freq 3
      pos 1180
      pos 4760
      pos 4942
    doc 10
      freq 1
      pos 11340
    doc 12
      freq 1
      pos 5980
    doc 13
      freq 3
      pos 1533
      pos 3566
      pos 3617
    doc 15
      freq 1
      pos 2427
  term becomes
    doc 2
      freq 1
      pos 1946
    doc 3
      freq 1
      pos 5287
    doc 10
      freq 1
      pos 1447
    doc 12
      freq 1
      pos 6712
    doc 13
      freq 2
      pos 4180
      pos 4732
    doc 17
      freq 1
      pos 1928
  term becoming
    doc 0
      freq 2
      pos 6480
      pos 9306
    doc 13
      freq 1
      pos 496
  term bed0b5
    doc 11
      freq 1
      pos 4006
  term been
    doc 0
      freq 15
      pos 1171
      pos 6147
      pos 6170
      pos 7487
      pos 8023
      pos 8076
      pos 8118
      pos 8171
      pos 8382
      pos 9361
      pos 12814
      pos 12861
      pos 12870
      pos 12951
      pos 15865
    doc 1
      freq 14
      pos 2403
      pos 2812
      pos 2911
      pos 2921
      pos 4345
      pos 4353
      pos 6507
      pos 6519
      pos 6637
      pos 6656
      pos 6966
      pos 7398
      pos 7543
      pos 8578
    doc 2
      freq 15
      pos 312
      pos 799
      pos 1112
      pos 1441
      pos 1666
      pos 1691
      pos 2106
      pos 2200
      pos 3955
      pos 4602
      pos 4845
      pos 5275
      pos 5963
      pos 5995
      pos 6003
    doc 3
      freq 3
      pos 391
      pos 3531
      pos 4200
    doc 4
      freq 2
      pos 2663
      pos 4838
    doc 5
      freq 5
      pos 163
      pos 377
      pos 386
      pos 805
      pos 829
    doc 6
      freq 3
      pos 301
      pos 771
      pos 2377
    doc 7
      freq 5
      pos 210
      pos 223
      pos 1277
      pos 1452
      pos 1770
    doc 8
      freq 1
      pos 83
    doc 9
      freq 1
      pos 1522
    doc 10
      freq 15
      pos 498
      pos 1035
      pos 1297
      pos 1317
      pos 1328
      pos 1973
      pos 3324
      pos 6804
      pos 9533
      pos 10946
      pos 11510
      pos 11610
      pos 11705
      pos 11806
      pos 11900
    doc 11
      freq 3
      pos 1856
      pos 2648
      pos 5257
    doc 12
      freq 24
      pos 726
      pos 881
      pos 1282
      pos 1632
      pos 1688
      pos 1829
      pos 1884
      pos 1913
      pos 2704
      pos 3295
      pos 3345
      pos 3729
      pos 3774
      pos 3780
      pos 3887
      pos 3904
      pos 4039
      pos 4676
      pos 4888
      pos 5548
      pos 5761
      pos 6513
      pos 6548
      pos 6894
    doc 13
      freq 8
      pos 393
      pos 421
      pos 442
      pos 465
      pos 794
      pos 1568
      pos 4039
      pos 5945
    doc 14
      freq 6
      pos 633
      pos 1198
      pos 1234
      pos 1249
      pos 1290
      pos 1348
    doc 15
      freq 8
      pos 118
      pos 333
      pos 356
      pos 825
      pos 837
      pos 1518
      pos 2632
      pos 3164
    doc 18
      freq 1
      pos 1938
    skipList 
      level 0
        skipDoc 7
        skipDocFP 497373
        impacts 
          impact 
            freq 5
            norm 100
          impact 
            freq 15
            norm 108
        impactsEnd 
        skipDoc 15
        skipDocFP 498483
        impacts 
          impact 
            freq 1
            norm 95
          impact 
            freq 8
            norm 104
          impact 
            freq 24
            norm 113
        impactsEnd 
  term beer
    doc 11
      freq 2
      pos 1146
      pos 1162
  term beeson
    doc 6
      freq 1
      pos 3099
  term befor
    doc 0
      freq 2
      pos 2682
      pos 10691
    doc 1
      freq 2
      pos 487
      pos 7631
    doc 2
      freq 2
      pos 4077
      pos 4548
    doc 3
      freq 4
      pos 1413
      pos 2529
      pos 2590
      pos 2754
    doc 4
      freq 2
      pos 1083
      pos 4620
    doc 5
      freq 2
      pos 554
      pos 1497
    doc 6
      freq 2
      pos 1648
      pos 1791
    doc 7
      freq 1
      pos 164
    doc 10
      freq 7
      pos 763
      pos 799
      pos 4736
      pos 5046
      pos 5662
      pos 7083
      pos 9160
    doc 12
      freq 2
      pos 3412
      pos 4845
    doc 13
      freq 1
      pos 3499
    doc 14
      freq 1
      pos 1766
    doc 18
      freq 6
      pos 659
      pos 772
      pos 790
      pos 836
      pos 1035
      pos 1985
    skipList 
      level 0
        skipDoc 7
        skipDocFP 500305
        impacts 
          impact 
            freq 1
            norm 100
          impact 
            freq 2
            norm 101
          impact 
            freq 4
            norm 107
        impactsEnd 
  term began
    doc 2
      freq 2
      pos 3513
      pos 4220
  term begin
    doc 0
      freq 1
      pos 1009
    doc 1
      freq 1
      pos 4326
    doc 10
      freq 6
      pos 6204
      pos 6246
      pos 6828
      pos 6877
      pos 12403
      pos 12450
    doc 11
      freq 2
      pos 9808
      pos 9871
    doc 17
      freq 1
      pos 2196
  term beginning
    doc 0
      freq 1
      pos 12700
    doc 5
      freq 1
      pos 1379
    doc 6
      freq 2
      pos 1649
      pos 1823
    doc 11
      freq 1
      pos 938
    doc 14
      freq 4
      pos 2589
      pos 2639
      pos 2670
      pos 2756
  term begins
    doc 3
      freq 1
      pos 3401
  term begun
    doc 2
      freq 1
      pos 5054
  term behalf
    doc 10
      freq 2
      pos 12920
      pos 12941
  term behav
    doc 11
      freq 1
      pos 9353
    doc 12
      freq 1
      pos 4448
    doc 15
      freq 1
      pos 2473
    doc 16
      freq 1
      pos 1171
  term behaves
    doc 1
      freq 1
      pos 6479
  term behavior
    doc 0
      freq 28
      pos 2102
      pos 2105
      pos 2108
      pos 2222
      pos 2225
      pos 2248
      pos 2251
      pos 2273
      pos 2569
      pos 2692
      pos 5749
      pos 5895
      pos 6918
      pos 6965
      pos 7048
      pos 7140
      pos 7183
      pos 10279
      pos 10493
      pos 10527
      pos 10590
      pos 10700
      pos 10784
      pos 11397
      pos 11523
      pos 11553
      pos 11587
      pos 11631
    doc 1
      freq 2
      pos 893
      pos 5870
    doc 3
      freq 2
      pos 5478
      pos 5844
    doc 4
      freq 1
      pos 516
    doc 6
      freq 5
      pos 515
      pos 549
      pos 756
      pos 986
      pos 2279
    doc 10
      freq 10
      pos 198
      pos 210
      pos 1738
      pos 2097
      pos 3216
      pos 3711
      pos 3793
      pos 4333
      pos 5874
      pos 10261
    doc 11
      freq 3
      pos 4584
      pos 8709
      pos 8800
    doc 12
      freq 6
      pos 458
      pos 2802
      pos 3060
      pos 3155
      pos 8075
      pos 8690
    doc 16
      freq 1
      pos 854
    skipList 
      level 0
        skipDoc 12
        skipDocFP 502437
        impacts 
          impact 
            freq 5
            norm 101
          impact 
            freq 6
            norm 113
          impact 
            freq 10
            norm 116
          impact 
            freq 28
            norm 120
        impactsEnd 
  term behaviors
    doc 0
      freq 5
      pos 10127
      pos 10188
      pos 10223
      pos 11426
      pos 11490
  term behaviour
    doc 15
      freq 2
      pos 2178
      pos 2922
  term beijnum
    doc 12
      freq 1
      pos 6810
  term being
    doc 0
      freq 2
      pos 4080
      pos 11888
    doc 1
      freq 8
      pos 2179
      pos 2187
      pos 3214
      pos 4583
      pos 4988
      pos 7583
      pos 8173
      pos 8390
    doc 2
      freq 1
      pos 4120
    doc 3
      freq 1
      pos 3328
    doc 4
      freq 3
      pos 4675
      pos 4726
      pos 5930
    doc 6
      freq 2
      pos 433
      pos 709
    doc 7
      freq 1
      pos 473
    doc 10
      freq 1
      pos 4964
    doc 11
      freq 1
      pos 2144
    doc 12
      freq 12
      pos 920
      pos 984
      pos 1455
      pos 1737
      pos 4355
      pos 5449
      pos 5514
      pos 5731
      pos 5828
      pos 6173
      pos 8940
      pos 9387
    doc 13
      freq 2
      pos 2046
      pos 6289
    doc 15
      freq 1
      pos 1181
    doc 17
      freq 1
      pos 1892
    doc 18
      freq 2
      pos 473
      pos 1915
    skipList 
      level 0
        skipDoc 10
        skipDocFP 504123
        impacts 
          impact 
            freq 1
            norm 100
          impact 
            freq 2
            norm 101
          impact 
            freq 3
            norm 108
          impact 
            freq 8
            norm 113
        impactsEnd 
  term bel
    doc 11
      freq 1
      pos 1943
  term belief
    doc 7
      freq 1
      pos 665
  term believ
    doc 4
      freq 1
      pos 4144
    doc 12
      freq 1
      pos 1028
  term believed
    doc 6
      freq 1
      pos 1004
  term believes
    doc 10
      freq 1
      pos 4437
  term bell
    doc 2
      freq 6
      pos 2986
      pos 3374
      pos 3460
      pos 4351
      pos 4426
      pos 4731
    doc 6
      freq 1
      pos 3126
    doc 11
      freq 3
      pos 6452
      pos 6613
      pos 6690
  term bellmansgatan
    doc 12
      freq 1
      pos 9444
    doc 18
      freq 1
      pos 2178
  term bellovin
    doc 9
      freq 1
      pos 1704
  term belong
    doc 4
      freq 2
      pos 1171
      pos 5671
  term belonging
    doc 4
      freq 2
      pos 1187
      pos 3929
  term belongs
    doc 0
      freq 1
      pos 9706
  term below
    doc 0
      freq 2
      pos 14437
      pos 14603
    doc 1
      freq 4
      pos 1700
      pos 3022
      pos 3046
      pos 4069
    doc 3
      freq 1
      pos 2182
    doc 5
      freq 4
      pos 1702
      pos 1914
      pos 1934
      pos 1977
    doc 6
      freq 2
      pos 647
      pos 890
    doc 7
      freq 1
      pos 458
    doc 8
      freq 4
      pos 625
      pos 1006
      pos 1299
      pos 1494
    doc 10
      freq 3
      pos 2495
      pos 5440
      pos 6047
    doc 12
      freq 4
      pos 5456
      pos 8193
      pos 8396
      pos 9081
    doc 16
      freq 2
      pos 1718
      pos 2136
    skipList 
      level 0
        skipDoc 10
        skipDocFP 506248
        impacts 
          impact 
            freq 4
            norm 97
        impactsEnd 
  term bemp3voqkmtqsmpjcxdmmytnzechh7wtob1yztsnzhfjcyj1ap3ss
    doc 10
      freq 1
      pos 12622
  term ben
    doc 11
      freq 1
      pos 9471
    doc 14
      freq 2
      pos 5526
      pos 5542
  term beneath
    doc 3
      freq 1
      pos 837
  term beneficial
    doc 12
      freq 1
      pos 3894
    doc 13
      freq 2
      pos 4149
      pos 4507
  term benefit
    doc 7
      freq 1
      pos 1159
    doc 13
      freq 2
      pos 2644
      pos 2670
  term benefits
    doc 13
      freq 1
      pos 2044
  term ber
    doc 0
      freq 2
      pos 2041
      pos 2076
  term berger
    doc 2
      freq 1
      pos 3186
  term bern
    doc 15
      freq 1
      pos 3843
  term bernard
    doc 2
      freq 8
      pos 365
      pos 2438
      pos 2757
      pos 2780
      pos 5197
      pos 6348
      pos 6376
      pos 6387
  term berners
    doc 11
      freq 1
      pos 9675
    doc 13
      freq 1
      pos 6895
  term berson
    doc 6
      freq 1
      pos 2874
  term bert
    doc 0
      freq 1
      pos 15971
    doc 2
      freq 2
      pos 360
      pos 2435
  term besprosvan
    doc 11
      freq 1
      pos 9434
  term best
    doc 3
      freq 2
      pos 3872
      pos 5689
    doc 4
      freq 1
      pos 1996
    doc 8
      freq 11
      pos 17
      pos 38
      pos 180
      pos 467
      pos 792
      pos 1119
      pos 1433
      pos 1663
      pos 1924
      pos 2147
      pos 2480
    doc 10
      freq 4
      pos 4553
      pos 9057
      pos 9318
      pos 9495
    doc 12
      freq 2
      pos 4532
      pos 6957
    doc 15
      freq 8
      pos 174
      pos 1884
      pos 2921
      pos 3061
      pos 3282
      pos 3685
      pos 3698
      pos 3768
    doc 18
      freq 1
      pos 872
  term better
    doc 2
      freq 1
      pos 4389
    doc 11
      freq 2
      pos 6848
      pos 6966
    doc 12
      freq 3
      pos 723
      pos 4849
      pos 6510
    doc 13
      freq 1
      pos 483
    doc 15
      freq 2
      pos 1197
      pos 3126
    doc 18
      freq 4
      pos 168
      pos 1068
      pos 1203
      pos 1987
  term between
    doc 0
      freq 25
      pos 511
      pos 2116
      pos 2491
      pos 2557
      pos 4837
      pos 6853
      pos 6873
      pos 6946
      pos 6996
      pos 7034
      pos 7113
      pos 7169
      pos 9212
      pos 9221
      pos 12896
      pos 13150
      pos 13252
      pos 13469
      pos 13567
      pos 13659
      pos 13761
      pos 13834
      pos 13906
      pos 14046
      pos 14175
    doc 1
      freq 4
      pos 1837
      pos 2008
      pos 7495
      pos 8313
    doc 2
      freq 23
      pos 100
      pos 319
      pos 340
      pos 773
      pos 1157
      pos 1729
      pos 2022
      pos 2532
      pos 2588
      pos 2629
      pos 2666
      pos 3508
      pos 3645
      pos 3878
      pos 4026
      pos 4328
      pos 4905
      pos 5316
      pos 5327
      pos 5597
      pos 6025
      pos 6073
      pos 6229
    doc 3
      freq 10
      pos 821
      pos 1058
      pos 1068
      pos 1088
      pos 1568
      pos 3161
      pos 3172
      pos 3884
      pos 4419
      pos 5641
    doc 5
      freq 9
      pos 131
      pos 424
      pos 492
      pos 1175
      pos 2176
      pos 2543
      pos 2861
      pos 2922
      pos 3295
    doc 6
      freq 2
      pos 1180
      pos 2287
    doc 7
      freq 2
      pos 914
      pos 2378
    doc 9
      freq 4
      pos 253
      pos 624
      pos 1224
      pos 1605
    doc 10
      freq 10
      pos 983
      pos 1387
      pos 1500
      pos 2845
      pos 4350
      pos 4407
      pos 5193
      pos 8968
      pos 10238
      pos 10745
    doc 11
      freq 9
      pos 178
      pos 892
      pos 907
      pos 1029
      pos 1227
      pos 2611
      pos 2632
      pos 5562
      pos 5722
    doc 12
      freq 10
      pos 2197
      pos 2240
      pos 3570
      pos 4618
      pos 5582
      pos 6260
      pos 6442
      pos 6918
      pos 8914
      pos 8986
    doc 13
      freq 15
      pos 1412
      pos 1474
      pos 1669
      pos 1751
      pos 2138
      pos 2199
      pos 2395
      pos 3208
      pos 3330
      pos 3468
      pos 4315
      pos 4963
      pos 5564
      pos 5602
      pos 6314
    doc 14
      freq 1
      pos 455
    doc 16
      freq 1
      pos 1151
    doc 17
      freq 2
      pos 1615
      pos 1640
    doc 18
      freq 3
      pos 207
      pos 232
      pos 1052
    skipList 
      level 0
        skipDoc 9
        skipDocFP 509177
        impacts 
          impact 
            freq 4
            norm 95
          impact 
            freq 9
            norm 104
          impact 
            freq 10
            norm 107
          impact 
            freq 23
            norm 108
          impact 
            freq 25
            norm 120
        impactsEnd 
        skipDoc 18
        skipDocFP 510548
        impacts 
          impact 
            freq 3
            norm 97
          impact 
            freq 15
            norm 109
        impactsEnd 
  term bext01
    doc 11
      freq 1
      pos 7732
  term bext01.0ha0isndaksdj
    doc 11
      freq 1
      pos 7751
  term beyond
    doc 2
      freq 1
      pos 1741
    doc 4
      freq 6
      pos 2180
      pos 2374
      pos 3349
      pos 3362
      pos 5086
      pos 5691
    doc 5
      freq 1
      pos 939
    doc 9
      freq 1
      pos 219
    doc 10
      freq 1
      pos 8091
    doc 11
      freq 1
      pos 2048
    doc 13
      freq 1
      pos 1807
  term bfeqb4aa
    doc 10
      freq 1
      pos 12821
  term bg
    doc 10
      freq 1
      pos 12760
  term bg6bge5nhafvfnk5n0dnt6n1nmf0mgt3ek3oxqvdiumzzrnohpxnof37w7w4lmsl
    doc 10
      freq 1
      pos 12482
  term bgnvbamme2f0bgfudgeuzxhhbxbszs5jb20whhcnmduxmdi0mdyznja2whcnmdyx
    doc 10
      freq 1
      pos 6250
  term bgp
    doc 0
      freq 1
      pos 11669
    doc 7
      freq 1
      pos 2882
  term bgp2
    doc 7
      freq 2
      pos 765
      pos 2155
  term bgp3
    doc 7
      freq 2
      pos 767
      pos 2157
  term bi
    doc 1
      freq 1
      pos 1673
    doc 13
      freq 4
      pos 1678
      pos 1710
      pos 1849
      pos 2274
  term bid
    doc 10
      freq 2
      pos 9490
      pos 9529
  term bidding
    doc 9
      freq 1
      pos 1567
  term bidirectional
    doc 1
      freq 3
      pos 3362
      pos 3572
      pos 4777
    doc 3
      freq 1
      pos 1346
  term big
    doc 0
      freq 2
      pos 2883
      pos 12521
    doc 4
      freq 7
      pos 194
      pos 772
      pos 1681
      pos 2756
      pos 2860
      pos 2908
      pos 2978
  term bigcod
    doc 11
      freq 1
      pos 6962
  term bigcode.asdof3uj203asdnf3429uasdhfas3ehjasdfas9
    doc 11
      freq 1
      pos 6980
  term bill
    doc 4
      freq 2
      pos 5476
      pos 5482
    doc 6
      freq 1
      pos 3104
    doc 18
      freq 1
      pos 2029
  term billeric
    doc 1
      freq 1
      pos 9318
    doc 3
      freq 1
      pos 4819
  term billing
    doc 10
      freq 1
      pos 8128
  term biloxi.cer
    doc 10
      freq 1
      pos 7377
  term biloxi.example.org
    doc 10
      freq 21
      pos 6299
      pos 6323
      pos 6337
      pos 6483
      pos 6608
      pos 6622
      pos 6827
      pos 6918
      pos 6951
      pos 6991
      pos 7039
      pos 7074
      pos 7128
      pos 7166
      pos 7231
      pos 7257
      pos 7285
      pos 7341
      pos 7376
      pos 7384
      pos 12308
  term bin
    doc 10
      freq 1
      pos 12392
    doc 11
      freq 1
      pos 9797
  term binary
    doc 10
      freq 1
      pos 12256
    doc 11
      freq 6
      pos 859
      pos 1002
      pos 3709
      pos 3832
      pos 3864
      pos 3875
    doc 14
      freq 1
      pos 2014
  term bind
    doc 1
      freq 1
      pos 787
  term binding
    doc 1
      freq 2
      pos 804
      pos 4896
    doc 7
      freq 1
      pos 2743
    doc 9
      freq 27
      pos 102
      pos 112
      pos 127
      pos 506
      pos 672
      pos 690
      pos 701
      pos 705
      pos 708
      pos 772
      pos 819
      pos 840
      pos 871
      pos 913
      pos 945
      pos 955
      pos 959
      pos 1022
      pos 1032
      pos 1143
      pos 1161
      pos 1187
      pos 1267
      pos 1282
      pos 1293
      pos 1331
      pos 1458
    doc 11
      freq 3
      pos 8693
      pos 8705
      pos 8910
    doc 17
      freq 3
      pos 1614
      pos 1634
      pos 1639
  term bindings
    doc 1
      freq 2
      pos 827
      pos 2055
  term binds
    doc 1
      freq 1
      pos 7474
  term bingzhang
    doc 0
      freq 1
      pos 15974
  term bis
    doc 11
      freq 1
      pos 9161
  term bit
    doc 0
      freq 15
      pos 1764
      pos 1771
      pos 1815
      pos 4952
      pos 4976
      pos 4982
      pos 5029
      pos 5057
      pos 5077
      pos 5120
      pos 10625
      pos 10629
      pos 11909
      pos 12206
      pos 13020
    doc 1
      freq 28
      pos 415
      pos 2352
      pos 2356
      pos 2359
      pos 2409
      pos 2506
      pos 2534
      pos 2537
      pos 2573
      pos 2631
      pos 2734
      pos 2908
      pos 4127
      pos 5115
      pos 5142
      pos 5176
      pos 5184
      pos 5839
      pos 6345
      pos 6700
      pos 6794
      pos 6898
      pos 6932
      pos 7836
      pos 7842
      pos 7847
      pos 9411
      pos 9484
    doc 3
      freq 3
      pos 2022
      pos 3057
      pos 3750
    doc 4
      freq 2
      pos 708
      pos 1261
    doc 5
      freq 4
      pos 1305
      pos 1331
      pos 1376
      pos 2376
    doc 6
      freq 9
      pos 595
      pos 601
      pos 617
      pos 633
      pos 672
      pos 1205
      pos 1482
      pos 2193
      pos 2842
    doc 8
      freq 8
      pos 498
      pos 829
      pos 1061
      pos 1157
      pos 1309
      pos 1338
      pos 1524
      pos 1582
    doc 9
      freq 1
      pos 1301
    doc 10
      freq 7
      pos 363
      pos 4892
      pos 5537
      pos 6165
      pos 9909
      pos 12151
      pos 12178
    doc 11
      freq 4
      pos 544
      pos 757
      pos 1102
      pos 9730
    doc 12
      freq 12
      pos 3826
      pos 6935
      pos 7633
      pos 8322
      pos 8353
      pos 8470
      pos 8566
      pos 8582
      pos 8592
      pos 8614
      pos 8662
      pos 8896
    doc 14
      freq 1
      pos 1833
    skipList 
      level 0
        skipDoc 9
        skipDocFP 515784
        impacts 
          impact 
            freq 1
            norm 95
          impact 
            freq 8
            norm 97
          impact 
            freq 9
            norm 101
          impact 
            freq 28
            norm 113
        impactsEnd 
  term bitlabels
    doc 12
      freq 1
      pos 816
  term bitmap
    doc 18
      freq 1
      pos 799
  term bits
    doc 0
      freq 10
      pos 1471
      pos 2035
      pos 2047
      pos 2070
      pos 2082
      pos 2944
      pos 3743
      pos 3744
      pos 4269
      pos 4270
    doc 1
      freq 1
      pos 5208
    doc 3
      freq 9
      pos 3681
      pos 3697
      pos 3720
      pos 3880
      pos 5230
      pos 5469
      pos 5512
      pos 5518
      pos 5672
    doc 4
      freq 2
      pos 1723
      pos 5617
    doc 5
      freq 9
      pos 1623
      pos 1644
      pos 1686
      pos 1720
      pos 1835
      pos 1844
      pos 2653
      pos 2662
      pos 2712
    doc 8
      freq 2
      pos 1530
      pos 1540
    doc 10
      freq 1
      pos 5212
    doc 11
      freq 4
      pos 949
      pos 990
      pos 1060
      pos 3284
    doc 12
      freq 1
      pos 5745
    doc 15
      freq 1
      pos 740
    doc 18
      freq 2
      pos 806
      pos 814
    skipList 
      level 0
        skipDoc 11
        skipDocFP 517930
        impacts 
          impact 
            freq 2
            norm 97
          impact 
            freq 9
            norm 104
          impact 
            freq 10
            norm 120
        impactsEnd 
  term bitwis
    doc 0
      freq 3
      pos 3832
      pos 4332
      pos 11196
  term bizarre.example.com
    doc 18
      freq 1
      pos 1066
  term black
    doc 12
      freq 1
      pos 2715
    doc 18
      freq 2
      pos 2022
      pos 2048
  term blameless
    doc 0
      freq 1
      pos 15855
  term blindly
    doc 11
      freq 1
      pos 8426
  term blkl8t
    doc 11
      freq 1
      pos 10383
  term blle2ix0jxzhitjb47viscgxwt15ekrpcz5
    doc 11
      freq 1
      pos 10013
  term block
    doc 0
      freq 1
      pos 1956
    doc 10
      freq 2
      pos 12188
      pos 12424
    doc 11
      freq 2
      pos 9740
      pos 9831
  term blocked
    doc 0
      freq 3
      pos 5940
      pos 5975
      pos 6066
  term blocks
    doc 5
      freq 1
      pos 2760
    doc 13
      freq 1
      pos 2157
  term blunk
    doc 2
      freq 2
      pos 2955
      pos 3266
  term blvd
    doc 1
      freq 1
      pos 9531
    doc 3
      freq 1
      pos 5896
    doc 6
      freq 1
      pos 3187
  term bmwg
    doc 2
      freq 1
      pos 6033
  term bnf
    doc 10
      freq 4
      pos 5075
      pos 5084
      pos 5103
      pos 13191
    doc 16
      freq 1
      pos 2612
  term bnpgtcol2k15i5x
    doc 11
      freq 1
      pos 10342
  term board
    doc 2
      freq 3
      pos 12
      pos 357
      pos 2233
    doc 12
      freq 1
      pos 7514
  term bob
    doc 2
      freq 1
      pos 6358
    doc 4
      freq 2
      pos 5488
      pos 5514
    doc 7
      freq 1
      pos 1788
    doc 10
      freq 14
      pos 2008
      pos 6298
      pos 6335
      pos 6620
      pos 6712
      pos 6739
      pos 6789
      pos 6916
      pos 6917
      pos 6989
      pos 7018
      pos 7027
      pos 7126
      pos 7339
    doc 11
      freq 1
      pos 9445
    doc 12
      freq 1
      pos 6766
    doc 16
      freq 2
      pos 1991
      pos 2056
  term bob's
    doc 10
      freq 3
      pos 2021
      pos 2077
      pos 7049
  term bocci
    doc 1
      freq 1
      pos 9057
    doc 8
      freq 1
      pos 1946
  term bodgey
    doc 11
      freq 1
      pos 9490
  term bodies
    doc 2
      freq 1
      pos 704
    doc 7
      freq 2
      pos 922
      pos 2386
    doc 10
      freq 7
      pos 1920
      pos 5235
      pos 8308
      pos 9076
      pos 9094
      pos 10192
      pos 13012
    doc 11
      freq 1
      pos 1004
    doc 16
      freq 1
      pos 2586
  term body
    doc 4
      freq 3
      pos 626
      pos 974
      pos 1503
    doc 10
      freq 19
      pos 241
      pos 251
      pos 2308
      pos 5205
      pos 5227
      pos 5240
      pos 5253
      pos 5267
      pos 5270
      pos 5340
      pos 6188
      pos 6801
      pos 6814
      pos 7190
      pos 9246
      pos 10128
      pos 10223
      pos 10308
      pos 13177
    doc 11
      freq 7
      pos 3234
      pos 3703
      pos 4367
      pos 7797
      pos 8979
      pos 9003
      pos 9219
    doc 13
      freq 2
      pos 3651
      pos 5573
    doc 16
      freq 7
      pos 771
      pos 788
      pos 814
      pos 1152
      pos 1283
      pos 1731
      pos 2223
  term bof
    doc 2
      freq 2
      pos 1100
      pos 5778
  term bogus
    doc 17
      freq 1
      pos 1430
  term bois
    doc 17
      freq 1
      pos 2394
  term bootstrapped
    doc 5
      freq 1
      pos 219
  term bootstrapping
    doc 5
      freq 26
      pos 17
      pos 205
      pos 250
      pos 353
      pos 565
      pos 572
      pos 789
      pos 929
      pos 1146
      pos 1477
      pos 1744
      pos 2047
      pos 2358
      pos 2555
      pos 2736
      pos 2811
      pos 3050
      pos 3224
      pos 3360
      pos 3501
      pos 3661
      pos 3677
      pos 3913
      pos 4113
      pos 4349
      pos 4434
  term border
    doc 1
      freq 1
      pos 8609
    doc 7
      freq 3
      pos 771
      pos 2013
      pos 2161
    doc 12
      freq 1
      pos 5553
  term borenstein
    doc 16
      freq 1
      pos 2574
  term bormann
    doc 13
      freq 1
      pos 6817
  term both
    doc 0
      freq 2
      pos 1881
      pos 7866
    doc 1
      freq 9
      pos 1694
      pos 1708
      pos 2399
      pos 2761
      pos 3440
      pos 5904
      pos 6201
      pos 6997
      pos 7980
    doc 2
      freq 8
      pos 1190
      pos 4176
      pos 4355
      pos 4465
      pos 4480
      pos 5515
      pos 5552
      pos 5558
    doc 3
      freq 6
      pos 1516
      pos 1765
      pos 2610
      pos 2676
      pos 2862
      pos 5078
    doc 4
      freq 1
      pos 1072
    doc 5
      freq 1
      pos 614
    doc 6
      freq 1
      pos 591
    doc 7
      freq 1
      pos 1228
    doc 9
      freq 1
      pos 186
    doc 10
      freq 4
      pos 810
      pos 3358
      pos 7796
      pos 10311
    doc 11
      freq 2
      pos 637
      pos 1237
    doc 12
      freq 10
      pos 114
      pos 1203
      pos 2154
      pos 2191
      pos 2665
      pos 2726
      pos 2923
      pos 2940
      pos 3719
      pos 8399
    doc 13
      freq 8
      pos 1331
      pos 1677
      pos 1967
      pos 2077
      pos 4288
      pos 5035
      pos 5587
      pos 6315
    doc 15
      freq 17
      pos 158
      pos 440
      pos 608
      pos 788
      pos 980
      pos 1001
      pos 1334
      pos 1793
      pos 1875
      pos 2265
      pos 2279
      pos 2432
      pos 2443
      pos 2778
      pos 3222
      pos 3382
      pos 3764
    doc 17
      freq 2
      pos 638
      pos 1217
    doc 18
      freq 1
      pos 1554
    skipList 
      level 0
        skipDoc 7
        skipDocFP 523164
        impacts 
          impact 
            freq 1
            norm 100
          impact 
            freq 6
            norm 107
          impact 
            freq 8
            norm 108
          impact 
            freq 9
            norm 113
        impactsEnd 
        skipDoc 18
        skipDocFP 523781
        impacts 
          impact 
            freq 1
            norm 95
          impact 
            freq 2
            norm 98
          impact 
            freq 17
            norm 104
        impactsEnd 
  term bottles
    doc 11
      freq 2
      pos 1144
      pos 1160
  term bottom
    doc 1
      freq 1
      pos 1752
  term boulevard
    doc 3
      freq 1
      pos 4907
  term bound
    doc 1
      freq 2
      pos 2137
      pos 2875
    doc 2
      freq 1
      pos 5362
    doc 3
      freq 4
      pos 529
      pos 532
      pos 5188
      pos 5814
    doc 4
      freq 1
      pos 5475
    doc 5
      freq 2
      pos 2433
      pos 3548
    doc 6
      freq 1
      pos 384
    doc 9
      freq 1
      pos 1574
    doc 12
      freq 2
      pos 7020
      pos 7174
    doc 13
      freq 1
      pos 1499
    doc 14
      freq 1
      pos 2620
    doc 15
      freq 1
      pos 3940
    skipList 
      level 0
        skipDoc 12
        skipDocFP 525423
        impacts 
          impact 
            freq 1
            norm 95
          impact 
            freq 2
            norm 104
          impact 
            freq 4
            norm 107
        impactsEnd 
  term boundaries
    doc 16
      freq 1
      pos 1150
  term boundary
    doc 11
      freq 1
      pos 3837
    doc 16
      freq 2
      pos 2022
      pos 2393
  term bounds
    doc 6
      freq 1
      pos 393
  term box
    doc 13
      freq 3
      pos 7013
      pos 7029
      pos 7048
  term boxborough
    doc 1
      freq 2
      pos 9388
      pos 9566
    doc 3
      freq 2
      pos 4774
      pos 5931
  term boxes
    doc 13
      freq 1
      pos 924
  term bp6fgel2n4gkkcx
    doc 11
      freq 1
      pos 9919
  term brackets
    doc 5
      freq 1
      pos 1195
    doc 11
      freq 3
      pos 5291
      pos 5303
      pos 6326
  term brad
    doc 6
      freq 1
      pos 3139
  term braden
    doc 4
      freq 1
      pos 5252
    doc 6
      freq 2
      pos 2870
      pos 2967
    doc 7
      freq 1
      pos 1789
  term bradley
    doc 2
      freq 1
      pos 2970
  term bradner
    doc 0
      freq 1
      pos 16942
    doc 1
      freq 1
      pos 8895
    doc 2
      freq 1
      pos 2251
    doc 3
      freq 1
      pos 4493
    doc 4
      freq 4
      pos 5268
      pos 5288
      pos 5305
      pos 5485
    doc 5
      freq 1
      pos 4123
    doc 7
      freq 1
      pos 1804
    doc 8
      freq 1
      pos 1763
    doc 9
      freq 1
      pos 1666
    doc 10
      freq 1
      pos 13117
    doc 12
      freq 1
      pos 7054
    doc 13
      freq 1
      pos 6736
    doc 17
      freq 1
      pos 2028
    doc 18
      freq 1
      pos 2127
    skipList 
      level 0
        skipDoc 8
        skipDocFP 527132
        impacts 
          impact 
            freq 1
            norm 97
          impact 
            freq 4
            norm 108
        impactsEnd 
  term branch
    doc 10
      freq 5
      pos 6332
      pos 6617
      pos 6983
      pos 7120
      pos 7333
    doc 11
      freq 58
      pos 1487
      pos 1514
      pos 1520
      pos 1657
      pos 1938
      pos 2228
      pos 2389
      pos 2580
      pos 2704
      pos 3139
      pos 3358
      pos 3392
      pos 3552
      pos 3644
      pos 3652
      pos 3660
      pos 3668
      pos 3676
      pos 3783
      pos 4014
      pos 4138
      pos 4479
      pos 4691
      pos 4911
      pos 5032
      pos 5186
      pos 5487
      pos 5647
      pos 5799
      pos 5971
      pos 6182
      pos 6372
      pos 6446
      pos 6607
      pos 6683
      pos 6791
      pos 6886
      pos 6976
      pos 7039
      pos 7083
      pos 7121
      pos 7220
      pos 7404
      pos 7535
      pos 7666
      pos 7769
      pos 7878
      pos 8064
      pos 8136
      pos 8326
      pos 8476
      pos 8483
      pos 8626
      pos 8735
      pos 8825
      pos 8942
      pos 9099
      pos 9181
  term branchvalu
    doc 11
      freq 1
      pos 3146
  term break
    doc 0
      freq 2
      pos 1477
      pos 16283
    doc 11
      freq 5
      pos 6408
      pos 6968
      pos 7050
      pos 7188
      pos 8105
  term breaking
    doc 13
      freq 1
      pos 3107
  term breaks
    doc 12
      freq 1
      pos 8757
  term brian
    doc 2
      freq 1
      pos 6352
    doc 4
      freq 1
      pos 5496
  term bridg
    doc 2
      freq 15
      pos 241
      pos 2835
      pos 3504
      pos 3546
      pos 3556
      pos 3576
      pos 3579
      pos 3650
      pos 4235
      pos 4285
      pos 4331
      pos 4362
      pos 4592
      pos 4635
      pos 4741
    doc 7
      freq 2
      pos 882
      pos 2346
  term bridged
    doc 2
      freq 1
      pos 2569
    doc 3
      freq 2
      pos 654
      pos 4461
  term bridges
    doc 2
      freq 5
      pos 2547
      pos 2911
      pos 3002
      pos 3380
      pos 3396
    doc 7
      freq 2
      pos 992
      pos 2480
  term bridging
    doc 3
      freq 2
      pos 1007
      pos 4158
  term brief
    doc 4
      freq 1
      pos 4121
    doc 8
      freq 1
      pos 413
    doc 12
      freq 1
      pos 585
  term briefly
    doc 12
      freq 1
      pos 734
  term bring
    doc 0
      freq 2
      pos 16262
      pos 17489
    doc 1
      freq 1
      pos 9870
    doc 2
      freq 1
      pos 6667
    doc 3
      freq 1
      pos 6219
    doc 4
      freq 1
      pos 6374
    doc 5
      freq 1
      pos 4704
    doc 6
      freq 1
      pos 3504
    doc 7
      freq 1
      pos 3209
    doc 8
      freq 1
      pos 2426
    doc 9
      freq 1
      pos 2071
    doc 10
      freq 1
      pos 13732
    doc 11
      freq 1
      pos 10893
    doc 12
      freq 1
      pos 9743
    doc 13
      freq 1
      pos 7358
    doc 14
      freq 1
      pos 5824
    doc 15
      freq 1
      pos 4343
    doc 16
      freq 1
      pos 2954
    doc 17
      freq 1
      pos 2678
    doc 18
      freq 1
      pos 2466
    skipList 
      level 0
        skipDoc 7
        skipDocFP 530211
        impacts 
          impact 
            freq 1
            norm 100
          impact 
            freq 2
            norm 120
        impactsEnd 
        skipDoc 15
        skipDocFP 530532
        impacts 
          impact 
            freq 1
            norm 95
        impactsEnd 
  term bringing
    doc 2
      freq 1
      pos 5518
  term brisco
    doc 5
      freq 1
      pos 4193
  term britiuwg5p5yxcsowqkukxvole7khehqbbtu0
    doc 10
      freq 1
      pos 12776
  term broad
    doc 15
      freq 1
      pos 1767
  term broadband
    doc 2
      freq 1
      pos 2723
    doc 13
      freq 6
      pos 189
      pos 2573
      pos 2588
      pos 2634
      pos 2664
      pos 2705
  term broadbus
    doc 6
      freq 1
      pos 3137
  term broadcast
    doc 0
      freq 4
      pos 635
      pos 5367
      pos 5722
      pos 6560
    doc 4
      freq 2
      pos 1771
      pos 2954
    doc 5
      freq 2
      pos 241
      pos 362
    doc 6
      freq 1
      pos 2911
    doc 11
      freq 3
      pos 466
      pos 8374
      pos 8434
    doc 13
      freq 2
      pos 725
      pos 2028
  term broadcasting
    doc 13
      freq 3
      pos 534
      pos 2669
      pos 6806
  term broadcasts
    doc 13
      freq 2
      pos 384
      pos 558
  term broadly
    doc 10
      freq 1
      pos 3397
  term broken
    doc 0
      freq 1
      pos 720
    doc 12
      freq 1
      pos 8253
  term broomfield
    doc 1
      freq 1
      pos 9532
    doc 3
      freq 1
      pos 5897
  term brought
    doc 0
      freq 1
      pos 16079
  term brown
    doc 2
      freq 1
      pos 2972
  term browsing
    doc 13
      freq 4
      pos 789
      pos 2502
      pos 2628
      pos 2653
  term bryant
    doc 1
      freq 1
      pos 9148
    doc 3
      freq 2
      pos 4311
      pos 4515
    doc 8
      freq 1
      pos 2100
  term btcbnzanbgkqhkig9w0baqefaaobjqawgykcgyeav6gwwc0td47jkwkljohjwfms
    doc 10
      freq 1
      pos 6885
  term bu
    doc 11
      freq 1
      pos 10317
  term bubb
    doc 3
      freq 1
      pos 4951
  term bucket
    doc 4
      freq 3
      pos 1896
      pos 1993
      pos 5603
    doc 6
      freq 3
      pos 2214
      pos 2219
      pos 2227
  term bucks
    doc 1
      freq 1
      pos 9550
    doc 3
      freq 1
      pos 5915
  term budget
    doc 2
      freq 1
      pos 4816
  term budgets
    doc 2
      freq 1
      pos 1175
  term buffer
    doc 0
      freq 2
      pos 2869
      pos 13985
    doc 3
      freq 1
      pos 5345
    doc 6
      freq 13
      pos 401
      pos 411
      pos 922
      pos 1584
      pos 1647
      pos 1673
      pos 1699
      pos 1703
      pos 1788
      pos 1803
      pos 2203
      pos 2420
      pos 2555
  term buffered
    doc 6
      freq 3
      pos 1310
      pos 1328
      pos 1476
  term buffering
    doc 6
      freq 1
      pos 1506
  term buffers
    doc 3
      freq 1
      pos 5387
    doc 6
      freq 1
      pos 2326
  term bug
    doc 11
      freq 1
      pos 2653
  term build
    doc 13
      freq 1
      pos 6426
  term building
    doc 5
      freq 1
      pos 2759
    doc 11
      freq 1
      pos 10596
  term built
    doc 5
      freq 1
      pos 1767
    doc 10
      freq 1
      pos 11122
  term bulk
    doc 7
      freq 2
      pos 121
      pos 301
  term bull
    doc 17
      freq 2
      pos 15
      pos 2386
  term bull.net
    doc 17
      freq 1
      pos 2398
  term bullet
    doc 4
      freq 1
      pos 5571
  term bunching
    doc 6
      freq 2
      pos 1603
      pos 2413
  term bundling
    doc 13
      freq 1
      pos 6722
  term buqe23p
    doc 10
      freq 1
      pos 12792
  term burgeoning
    doc 6
      freq 1
      pos 875
  term burst
    doc 4
      freq 1
      pos 1932
    doc 13
      freq 1
      pos 2162
  term burstiness
    doc 6
      freq 1
      pos 2486
  term bursts
    doc 13
      freq 1
      pos 4120
  term bursty
    doc 4
      freq 1
      pos 1950
  term bush
    doc 12
      freq 4
      pos 7039
      pos 7052
      pos 7159
      pos 7197
    doc 14
      freq 1
      pos 5395
  term business
    doc 8
      freq 1
      pos 454
  term but
    doc 0
      freq 9
      pos 1563
      pos 5854
      pos 9200
      pos 12970
      pos 13805
      pos 14420
      pos 14586
      pos 14795
      pos 17302
    doc 1
      freq 18
      pos 708
      pos 3442
      pos 3802
      pos 4257
      pos 4585
      pos 4768
      pos 5596
      pos 6509
      pos 6820
      pos 6835
      pos 6875
      pos 6941
      pos 7049
      pos 7276
      pos 8272
      pos 8676
      pos 8775
      pos 9683
    doc 2
      freq 4
      pos 3796
      pos 3986
      pos 4789
      pos 6480
    doc 3
      freq 6
      pos 1196
      pos 2003
      pos 5214
      pos 5414
      pos 5465
      pos 6032
    doc 4
      freq 4
      pos 1920
      pos 4261
      pos 4703
      pos 6187
    doc 5
      freq 3
      pos 641
      pos 1894
      pos 4517
    doc 6
      freq 3
      pos 627
      pos 2379
      pos 3317
    doc 7
      freq 3
      pos 1147
      pos 1204
      pos 3022
    doc 8
      freq 2
      pos 1709
      pos 2239
    doc 9
      freq 1
      pos 1884
    doc 10
      freq 11
      pos 2226
      pos 2486
      pos 4385
      pos 5254
      pos 7561
      pos 7943
      pos 9812
      pos 9981
      pos 10918
      pos 11422
      pos 13545
    doc 11
      freq 12
      pos 418
      pos 688
      pos 846
      pos 1652
      pos 3253
      pos 4422
      pos 4867
      pos 6515
      pos 6840
      pos 7041
      pos 7414
      pos 10706
    doc 12
      freq 22
      pos 1285
      pos 1493
      pos 1645
      pos 1845
      pos 1886
      pos 2133
      pos 2446
      pos 2669
      pos 3106
      pos 3208
      pos 3702
      pos 3776
      pos 3841
      pos 4511
      pos 5366
      pos 5830
      pos 6465
      pos 8168
      pos 8354
      pos 8587
      pos 8609
      pos 9556
    doc 13
      freq 6
      pos 433
      pos 631
      pos 2284
      pos 4160
      pos 5289
      pos 7171
    doc 14
      freq 4
      pos 2434
      pos 2633
      pos 2677
      pos 5637
    doc 15
      freq 6
      pos 966
      pos 1740
      pos 2130
      pos 3197
      pos 3678
      pos 4156
    doc 16
      freq 1
      pos 2767
    doc 17
      freq 4
      pos 248
      pos 1543
      pos 1907
      pos 2491
    doc 18
      freq 8
      pos 561
      pos 775
      pos 789
      pos 857
      pos 1160
      pos 1905
      pos 1927
      pos 2279
    skipList 
      level 0
        skipDoc 7
        skipDocFP 535205
        impacts 
          impact 
            freq 3
            norm 100
          impact 
            freq 6
            norm 107
          impact 
            freq 18
            norm 113
        impactsEnd 
        skipDoc 15
        skipDocFP 536143
        impacts 
          impact 
            freq 1
            norm 95
          impact 
            freq 2
            norm 97
          impact 
            freq 6
            norm 104
          impact 
            freq 22
            norm 113
        impactsEnd 
  term bvcp
    doc 7
      freq 2
      pos 1085
      pos 2678
  term bws4jod2qsuehftp8axsremup0mrlxp
    doc 10
      freq 1
      pos 12523
  term bxmhegm
    doc 11
      freq 1
      pos 10442
  term by
    doc 0
      freq 76
      pos 740
      pos 750
      pos 806
      pos 907
      pos 1165
      pos 1359
      pos 1458
      pos 1666
      pos 2560
      pos 2889
      pos 2966
      pos 3344
      pos 3381
      pos 3431
      pos 3544
      pos 3751
      pos 3760
      pos 3944
      pos 3975
      pos 4062
      pos 4254
      pos 4277
      pos 4772
      pos 4849
      pos 4934
      pos 5423
      pos 5775
      pos 5861
      pos 6290
      pos 6519
      pos 6794
      pos 6817
      pos 7367
      pos 7402
      pos 7435
      pos 7788
      pos 8000
      pos 8954
      pos 9463
      pos 9646
      pos 9781
      pos 9808
      pos 9840
      pos 9870
      pos 10299
      pos 10419
      pos 10740
      pos 10833
      pos 11137
      pos 11335
      pos 11373
      pos 11890
      pos 11974
      pos 12547
      pos 12617
      pos 12770
      pos 12822
      pos 12874
      pos 12955
      pos 13384
      pos 15662
      pos 15848
      pos 16035
      pos 16050
      pos 16085
      pos 16204
      pos 16248
      pos 16414
      pos 16500
      pos 16519
      pos 16537
      pos 16727
      pos 16766
      pos 17283
      pos 17461
      pos 17535
    doc 1
      freq 36
      pos 125
      pos 704
      pos 1241
      pos 1451
      pos 1487
      pos 3011
      pos 3039
      pos 3286
      pos 3410
      pos 3775
      pos 4374
      pos 4442
      pos 4503
      pos 4674
      pos 4749
      pos 4938
      pos 5166
      pos 5825
      pos 5891
      pos 5940
      pos 6902
      pos 7352
      pos 7400
      pos 7407
      pos 7545
      pos 7585
      pos 7767
      pos 7817
      pos 8278
      pos 8291
      pos 8333
      pos 8746
      pos 8790
      pos 9664
      pos 9842
      pos 9916
    doc 2
      freq 33
      pos 466
      pos 513
      pos 587
      pos 649
      pos 720
      pos 836
      pos 848
      pos 1083
      pos 1225
      pos 1279
      pos 1288
      pos 1444
      pos 1835
      pos 1908
      pos 2057
      pos 3597
      pos 3819
      pos 3905
      pos 4208
      pos 4261
      pos 4272
      pos 4551
      pos 4815
      pos 4982
      pos 5080
      pos 5118
      pos 5491
      pos 5872
      pos 5880
      pos 6318
      pos 6461
      pos 6639
      pos 6713
    doc 3
      freq 26
      pos 394
      pos 1487
      pos 1573
      pos 1579
      pos 1605
      pos 1669
      pos 1727
      pos 2034
      pos 2268
      pos 2365
      pos 2378
      pos 2453
      pos 2476
      pos 2516
      pos 2523
      pos 2564
      pos 2989
      pos 2997
      pos 3595
      pos 3601
      pos 3944
      pos 4121
      pos 4131
      pos 6013
      pos 6191
      pos 6265
    doc 4
      freq 33
      pos 479
      pos 518
      pos 525
      pos 538
      pos 554
      pos 701
      pos 1161
      pos 1214
      pos 1809
      pos 1832
      pos 2218
      pos 2223
      pos 2234
      pos 2238
      pos 2513
      pos 2838
      pos 2843
      pos 2864
      pos 3105
      pos 3110
      pos 4166
      pos 4217
      pos 4302
      pos 4317
      pos 4363
      pos 4386
      pos 4477
      pos 4520
      pos 4840
      pos 6025
      pos 6168
      pos 6346
      pos 6420
    doc 5
      freq 22
      pos 143
      pos 188
      pos 229
      pos 481
      pos 732
      pos 814
      pos 1042
      pos 1660
      pos 1769
      pos 1882
      pos 3121
      pos 3258
      pos 3398
      pos 3632
      pos 3709
      pos 3793
      pos 3864
      pos 3892
      pos 4009
      pos 4498
      pos 4676
      pos 4750
    doc 6
      freq 15
      pos 87
      pos 367
      pos 389
      pos 435
      pos 882
      pos 940
      pos 975
      pos 1118
      pos 2254
      pos 2565
      pos 2599
      pos 2710
      pos 3298
      pos 3476
      pos 3550
    doc 7
      freq 4
      pos 346
      pos 3003
      pos 3181
      pos 3255
    doc 8
      freq 15
      pos 239
      pos 250
      pos 522
      pos 569
      pos 852
      pos 900
      pos 1178
      pos 1225
      pos 1359
      pos 1406
      pos 1548
      pos 1715
      pos 2220
      pos 2398
      pos 2472
    doc 9
      freq 6
      pos 923
      pos 1253
      pos 1275
      pos 1865
      pos 2043
      pos 2117
    doc 10
      freq 94
      pos 136
      pos 523
      pos 571
      pos 723
      pos 737
      pos 843
      pos 877
      pos 931
      pos 970
      pos 1285
      pos 1497
      pos 1712
      pos 1856
      pos 2043
      pos 2076
      pos 2118
      pos 2170
      pos 2217
      pos 2421
      pos 2578
      pos 2675
      pos 2710
      pos 3075
      pos 3194
      pos 3204
      pos 3406
      pos 3437
      pos 3524
      pos 3572
      pos 3869
      pos 3988
      pos 4022
      pos 4132
      pos 4381
      pos 4394
      pos 4901
      pos 4988
      pos 5281
      pos 5430
      pos 5669
      pos 5868
      pos 6073
      pos 6415
      pos 6771
      pos 7019
      pos 7587
      pos 7843
      pos 7919
      pos 8006
      pos 8061
      pos 8323
      pos 8674
      pos 8688
      pos 8848
      pos 9319
      pos 9349
      pos 9374
      pos 9739
      pos 9822
      pos 10019
      pos 10035
      pos 10195
      pos 10427
      pos 10459
      pos 10753
      pos 10834
      pos 10887
      pos 10948
      pos 10953
      pos 10969
      pos 11015
      pos 11021
      pos 11038
      pos 11106
      pos 11176
      pos 11362
      pos 11504
      pos 11604
      pos 11672
      pos 11681
      pos 11688
      pos 11699
      pos 11762
      pos 11780
      pos 11800
      pos 11886
      pos 11894
      pos 12428
      pos 12888
      pos 12989
      pos 13068
      pos 13526
      pos 13704
      pos 13778
    doc 11
      freq 12
      pos 901
      pos 3943
      pos 6575
      pos 7032
      pos 8392
      pos 9167
      pos 9432
      pos 9464
      pos 9835
      pos 10687
      pos 10865
      pos 10939
    doc 12
      freq 26
      pos 1482
      pos 1730
      pos 1864
      pos 2009
      pos 2424
      pos 3085
      pos 4175
      pos 4384
      pos 4392
      pos 4731
      pos 5059
      pos 5067
      pos 5108
      pos 5301
      pos 5408
      pos 5670
      pos 5846
      pos 5942
      pos 6762
      pos 7803
      pos 8187
      pos 9004
      pos 9409
      pos 9537
      pos 9715
      pos 9789
    doc 13
      freq 34
      pos 472
      pos 842
      pos 850
      pos 908
      pos 1257
      pos 1541
      pos 1612
      pos 1957
      pos 2082
      pos 2327
      pos 2392
      pos 2467
      pos 2973
      pos 3261
      pos 3266
      pos 3343
      pos 4575
      pos 4591
      pos 4849
      pos 5352
      pos 5515
      pos 5629
      pos 5693
      pos 6027
      pos 6291
      pos 6358
      pos 6454
      pos 6485
      pos 6495
      pos 6563
      pos 6620
      pos 7152
      pos 7330
      pos 7404
    doc 14
      freq 11
      pos 635
      pos 1838
      pos 2186
      pos 2560
      pos 2942
      pos 3561
      pos 4529
      pos 5303
      pos 5618
      pos 5796
      pos 5870
    doc 15
      freq 18
      pos 120
      pos 480
      pos 490
      pos 726
      pos 923
      pos 1118
      pos 1139
      pos 1936
      pos 2351
      pos 2899
      pos 2908
      pos 2927
      pos 3128
      pos 3210
      pos 3314
      pos 4137
      pos 4315
      pos 4389
    doc 16
      freq 13
      pos 459
      pos 495
      pos 749
      pos 765
      pos 775
      pos 1561
      pos 1645
      pos 1958
      pos 2142
      pos 2326
      pos 2748
      pos 2926
      pos 3000
    doc 17
      freq 25
      pos 203
      pos 213
      pos 393
      pos 504
      pos 557
      pos 574
      pos 645
      pos 665
      pos 727
      pos 828
      pos 975
      pos 991
      pos 1025
      pos 1119
      pos 1126
      pos 1240
      pos 1380
      pos 1768
      pos 1951
      pos 1973
      pos 1984
      pos 2336
      pos 2472
      pos 2650
      pos 2724
    doc 18
      freq 11
      pos 113
      pos 116
      pos 138
      pos 285
      pos 307
      pos 1613
      pos 1944
      pos 1978
      pos 2260
      pos 2438
      pos 2512
    skipList 
      level 0
        skipDoc 7
        skipDocFP 538360
        impacts 
          impact 
            freq 4
            norm 100
          impact 
            freq 15
            norm 101
          impact 
            freq 22
            norm 104
          impact 
            freq 26
            norm 107
          impact 
            freq 33
            norm 108
          impact 
            freq 36
            norm 113
          impact 
            freq 76
            norm 120
        impactsEnd 
        skipDoc 15
        skipDocFP 542223
        impacts 
          impact 
            freq 6
            norm 95
          impact 
            freq 15
            norm 97
          impact 
            freq 18
            norm 104
          impact 
            freq 34
            norm 109
          impact 
            freq 94
            norm 116
        impactsEnd 
  term bye
    doc 10
      freq 13
      pos 5788
      pos 5818
      pos 6924
      pos 6944
      pos 6972
      pos 7005
      pos 7015
      pos 7109
      pos 7151
      pos 7236
      pos 7322
      pos 7364
      pos 8681
  term bypass
    doc 12
      freq 1
      pos 5140
  term byte
    doc 0
      freq 10
      pos 1504
      pos 1514
      pos 1522
      pos 1540
      pos 6513
      pos 6682
      pos 9157
      pos 11831
      pos 12715
      pos 14348
    doc 1
      freq 2
      pos 3761
      pos 3779
    doc 5
      freq 5
      pos 2009
      pos 2019
      pos 2086
      pos 2112
      pos 2692
    doc 6
      freq 1
      pos 2092
    doc 7
      freq 1
      pos 1857
  term bytes
    doc 0
      freq 4
      pos 2857
      pos 12399
      pos 13056
      pos 14224
    doc 3
      freq 1
      pos 4230
    doc 5
      freq 6
      pos 1853
      pos 1948
      pos 1955
      pos 1961
      pos 1970
      pos 2716
    doc 6
      freq 2
      pos 1272
      pos 1332
    doc 8
      freq 1
      pos 1043
    doc 10
      freq 2
      pos 2305
      pos 6581
  term c.example.com
    doc 11
      freq 4
      pos 6605
      pos 6628
      pos 6682
      pos 6704
  term c.m
    doc 2
      freq 1
      pos 3247
  term c1hz8u9oj5
    doc 11
      freq 1
      pos 10297
  term c3f
    doc 10
      freq 1
      pos 12732
  term c6
    doc 11
      freq 1
      pos 10050
  term c6m4k3dpmtfailai9bppu1ek2euxfauqqhrx5wfhmuuidvrcnkvr4
    doc 11
      freq 1
      pos 10142
  term c7c0cff9172f3b027e4fc027e1546de4
    doc 11
      freq 1
      pos 3910
  term c8jsv
    doc 11
      freq 1
      pos 10329
  term ca
    doc 1
      freq 6
      pos 9212
      pos 9245
      pos 9292
      pos 9306
      pos 9361
      pos 9375
    doc 3
      freq 6
      pos 4761
      pos 4865
      pos 4895
      pos 4954
      pos 4968
      pos 4982
    doc 4
      freq 2
      pos 6069
      pos 6083
    doc 9
      freq 1
      pos 1775
    doc 10
      freq 3
      pos 4092
      pos 13415
      pos 13443
    doc 16
      freq 1
      pos 2660
    doc 17
      freq 4
      pos 174
      pos 190
      pos 1715
      pos 1728
  term caballer
    doc 11
      freq 1
      pos 9598
  term cable
    doc 6
      freq 3
      pos 883
      pos 3112
      pos 3158
    doc 13
      freq 1
      pos 545
  term cable.comcast.com
    doc 12
      freq 1
      pos 9440
  term cablelabs
    doc 6
      freq 1
      pos 2920
  term caceres
    doc 6
      freq 1
      pos 3046
  term cache
    doc 9
      freq 1
      pos 1033
    doc 12
      freq 4
      pos 2956
      pos 3011
      pos 3104
      pos 3147
    doc 18
      freq 1
      pos 962
  term cached
    doc 10
      freq 2
      pos 2618
      pos 3981
    doc 12
      freq 1
      pos 3582
    doc 13
      freq 1
      pos 4812
  term caches
    doc 12
      freq 3
      pos 1180
      pos 3131
      pos 9013
  term caching
    doc 12
      freq 4
      pos 2805
      pos 2902
      pos 2971
      pos 9179
    doc 13
      freq 1
      pos 665
  term calculat
    doc 6
      freq 1
      pos 610
    doc 10
      freq 1
      pos 7054
  term calculated
    doc 6
      freq 2
      pos 1947
      pos 2005
    doc 10
      freq 1
      pos 11885
    doc 12
      freq 1
      pos 5889
    doc 14
      freq 1
      pos 356
  term calculates
    doc 10
      freq 1
      pos 6448
  term calculating
    doc 4
      freq 1
      pos 1084
    doc 6
      freq 2
      pos 1973
      pos 2015
    doc 10
      freq 1
      pos 7084
  term calculation
    doc 4
      freq 4
      pos 174
      pos 1255
      pos 4265
      pos 5771
    doc 6
      freq 5
      pos 666
      pos 1325
      pos 1693
      pos 1717
      pos 2302
    doc 9
      freq 1
      pos 993
  term calculations
    doc 6
      freq 2
      pos 2469
      pos 2560
  term calgary
    doc 11
      freq 1
      pos 10544
  term calhoun
    doc 2
      freq 2
      pos 3096
      pos 3140
  term call
    doc 1
      freq 1
      pos 1467
    doc 2
      freq 3
      pos 1104
      pos 5524
      pos 5531
    doc 7
      freq 4
      pos 525
      pos 1489
      pos 1500
      pos 2736
    doc 8
      freq 1
      pos 388
    doc 10
      freq 19
      pos 617
      pos 766
      pos 4254
      pos 4543
      pos 4715
      pos 4970
      pos 6344
      pos 6629
      pos 7000
      pos 7146
      pos 7359
      pos 8227
      pos 8531
      pos 8545
      pos 8570
      pos 8577
      pos 8586
      pos 8618
      pos 8760
    doc 11
      freq 54
      pos 1472
      pos 1756
      pos 1980
      pos 2376
      pos 2571
      pos 2691
      pos 2771
      pos 2875
      pos 3379
      pos 3526
      pos 3629
      pos 3762
      pos 3822
      pos 4016
      pos 4140
      pos 4287
      pos 4466
      pos 4679
      pos 4924
      pos 5048
      pos 5170
      pos 5328
      pos 5473
      pos 5634
      pos 5811
      pos 5951
      pos 6169
      pos 6359
      pos 6463
      pos 6624
      pos 6700
      pos 6779
      pos 6871
      pos 6978
      pos 7126
      pos 7174
      pos 7392
      pos 7523
      pos 7648
      pos 7749
      pos 7866
      pos 8053
      pos 8089
      pos 8144
      pos 8151
      pos 8336
      pos 8485
      pos 8614
      pos 8748
      pos 8838
      pos 8929
      pos 9084
      pos 9274
      pos 9703
    doc 12
      freq 1
      pos 6823
  term callback
    doc 10
      freq 1
      pos 11276
  term called
    doc 1
      freq 2
      pos 5574
      pos 7257
    doc 2
      freq 1
      pos 1692
    doc 3
      freq 1
      pos 5295
    doc 4
      freq 1
      pos 310
    doc 10
      freq 5
      pos 2107
      pos 3804
      pos 8781
      pos 11954
      pos 12036
    doc 12
      freq 1
      pos 1333
    doc 18
      freq 4
      pos 111
      pos 273
      pos 537
      pos 895
  term caller
    doc 10
      freq 5
      pos 637
      pos 753
      pos 757
      pos 9583
      pos 9589
    doc 11
      freq 1
      pos 2683
  term callid
    doc 10
      freq 2
      pos 4968
      pos 5330
  term callon
    doc 0
      freq 1
      pos 16961
    doc 3
      freq 1
      pos 4392
  term calls
    doc 11
      freq 1
      pos 656
    doc 12
      freq 1
      pos 2819
  term camarill
    doc 5
      freq 1
      pos 4320
    doc 10
      freq 1
      pos 13095
    doc 11
      freq 2
      pos 9470
      pos 9634
    doc 13
      freq 2
      pos 6833
      pos 6963
  term cambridg
    doc 1
      freq 1
      pos 9194
  term cambridgepark
    doc 1
      freq 1
      pos 9192
  term came
    doc 4
      freq 1
      pos 4147
    doc 15
      freq 1
      pos 1252
  term cameras
    doc 13
      freq 1
      pos 926
  term campbell
    doc 11
      freq 1
      pos 9472
  term can
    doc 0
      freq 24
      pos 2918
      pos 3566
      pos 5568
      pos 6088
      pos 10358
      pos 12767
      pos 14783
      pos 14791
      pos 16152
      pos 16188
      pos 16201
      pos 16257
      pos 16279
      pos 16332
      pos 16362
      pos 16383
      pos 16421
      pos 16494
      pos 16524
      pos 16549
      pos 16582
      pos 16620
      pos 17413
      pos 17468
    doc 1
      freq 23
      pos 118
      pos 909
      pos 927
      pos 940
      pos 1232
      pos 1293
      pos 1943
      pos 2901
      pos 3070
      pos 3390
      pos 3407
      pos 3479
      pos 3772
      pos 4059
      pos 4149
      pos 5148
      pos 5163
      pos 5465
      pos 6262
      pos 7120
      pos 7428
      pos 9794
      pos 9849
    doc 2
      freq 12
      pos 584
      pos 604
      pos 852
      pos 875
      pos 1028
      pos 1359
      pos 1507
      pos 1512
      pos 1804
      pos 2031
      pos 6591
      pos 6646
    doc 3
      freq 16
      pos 1462
      pos 1484
      pos 1570
      pos 1585
      pos 1600
      pos 2247
      pos 2345
      pos 2968
      pos 3726
      pos 4118
      pos 5068
      pos 5088
      pos 5181
      pos 5290
      pos 6143
      pos 6198
    doc 4
      freq 22
      pos 1408
      pos 1907
      pos 2323
      pos 2390
      pos 2746
      pos 2992
      pos 3228
      pos 3364
      pos 3531
      pos 4009
      pos 4033
      pos 4058
      pos 4110
      pos 4163
      pos 4214
      pos 4425
      pos 4516
      pos 4544
      pos 4857
      pos 5625
      pos 6298
      pos 6353
    doc 5
      freq 14
      pos 607
      pos 679
      pos 718
      pos 1102
      pos 1135
      pos 1789
      pos 1877
      pos 2593
      pos 2948
      pos 2994
      pos 3582
      pos 3629
      pos 4628
      pos 4683
    doc 6
      freq 15
      pos 186
      pos 532
      pos 639
      pos 724
      pos 987
      pos 2303
      pos 2479
      pos 2491
      pos 2507
      pos 2551
      pos 2575
      pos 2594
      pos 2620
      pos 3428
      pos 3483
    doc 7
      freq 4
      pos 495
      pos 1758
      pos 3133
      pos 3188
    doc 8
      freq 3
      pos 215
      pos 2350
      pos 2405
    doc 9
      freq 8
      pos 106
      pos 269
      pos 326
      pos 533
      pos 695
      pos 1189
      pos 1995
      pos 2050
    doc 10
      freq 49
      pos 467
      pos 520
      pos 614
      pos 651
      pos 839
      pos 1075
      pos 1090
      pos 1093
      pos 1131
      pos 1338
      pos 1422
      pos 1648
      pos 2037
      pos 2115
      pos 2159
      pos 2292
      pos 2661
      pos 2683
      pos 2696
      pos 2876
      pos 2897
      pos 3159
      pos 3350
      pos 3474
      pos 4316
      pos 4575
      pos 4624
      pos 4780
      pos 5789
      pos 5819
      pos 6790
      pos 7593
      pos 7794
      pos 7810
      pos 7964
      pos 8574
      pos 9306
      pos 9391
      pos 9527
      pos 9754
      pos 10314
      pos 10831
      pos 10850
      pos 11212
      pos 11358
      pos 12425
      pos 12885
      pos 13656
      pos 13711
    doc 11
      freq 10
      pos 1130
      pos 2418
      pos 2431
      pos 4198
      pos 4558
      pos 4627
      pos 8288
      pos 9832
      pos 10817
      pos 10872
    doc 12
      freq 27
      pos 924
      pos 1071
      pos 2234
      pos 2299
      pos 3650
      pos 3747
      pos 3975
      pos 3994
      pos 4105
      pos 4266
      pos 4278
      pos 4380
      pos 4470
      pos 4874
      pos 5266
      pos 5518
      pos 5533
      pos 5611
      pos 5934
      pos 5975
      pos 6357
      pos 8162
      pos 8178
      pos 8268
      pos 8296
      pos 9667
      pos 9722
    doc 13
      freq 33
      pos 575
      pos 858
      pos 903
      pos 1052
      pos 1253
      pos 1836
      pos 1953
      pos 2041
      pos 2218
      pos 2387
      pos 2471
      pos 2881
      pos 2966
      pos 2996
      pos 3032
      pos 3144
      pos 3364
      pos 3411
      pos 3423
      pos 3434
      pos 3442
      pos 3455
      pos 3491
      pos 3856
      pos 4147
      pos 4427
      pos 4469
      pos 4487
      pos 4758
      pos 4770
      pos 4858
      pos 7282
      pos 7337
    doc 14
      freq 6
      pos 1373
      pos 2017
      pos 2274
      pos 2543
      pos 5748
      pos 5803
    doc 15
      freq 12
      pos 745
      pos 1235
      pos 1547
      pos 1651
      pos 2207
      pos 2324
      pos 2385
      pos 2946
      pos 3013
      pos 3333
      pos 4267
      pos 4322
    doc 16
      freq 15
      pos 135
      pos 198
      pos 243
      pos 285
      pos 372
      pos 421
      pos 549
      pos 1213
      pos 1429
      pos 1751
      pos 1872
      pos 2130
      pos 2292
      pos 2878
      pos 2933
    doc 17
      freq 7
      pos 135
      pos 175
      pos 1234
      pos 1685
      pos 1839
      pos 2602
      pos 2657
    doc 18
      freq 5
      pos 127
      pos 317
      pos 585
      pos 2390
      pos 2445
    skipList 
      level 0
        skipDoc 7
        skipDocFP 554109
        impacts 
          impact 
            freq 4
            norm 100
          impact 
            freq 15
            norm 101
          impact 
            freq 16
            norm 107
          impact 
            freq 22
            norm 108
          impact 
            freq 23
            norm 113
          impact 
            freq 24
            norm 120
        impactsEnd 
        skipDoc 15
        skipDocFP 556253
        impacts 
          impact 
            freq 8
            norm 95
          impact 
            freq 12
            norm 104
          impact 
            freq 33
            norm 109
          impact 
            freq 49
            norm 116
        impactsEnd 
  term can't
    doc 15
      freq 1
      pos 2744
    doc 16
      freq 2
      pos 603
      pos 618
  term canad
    doc 2
      freq 1
      pos 376
    doc 3
      freq 1
      pos 4879
    doc 6
      freq 1
      pos 3127
    doc 11
      freq 1
      pos 10548
  term cancel
    doc 10
      freq 4
      pos 5856
      pos 5859
      pos 5876
      pos 5938
  term candidat
    doc 6
      freq 1
      pos 68
  term candidates
    doc 7
      freq 1
      pos 520
  term canett
    doc 5
      freq 3
      pos 4075
      pos 4187
      pos 4258
  term cannon
    doc 11
      freq 1
      pos 9573
  term cannot
    doc 0
      freq 14
      pos 747
      pos 3301
      pos 3652
      pos 3908
      pos 4168
      pos 4420
      pos 5614
      pos 5704
      pos 10139
      pos 11010
      pos 11438
      pos 14409
      pos 14575
      pos 14796
    doc 1
      freq 1
      pos 4526
    doc 3
      freq 1
      pos 2951
    doc 4
      freq 6
      pos 1947
      pos 2252
      pos 2428
      pos 2450
      pos 2874
      pos 3399
    doc 5
      freq 1
      pos 3074
    doc 10
      freq 17
      pos 874
      pos 967
      pos 4052
      pos 4121
      pos 4611
      pos 5861
      pos 7840
      pos 8015
      pos 9032
      pos 9257
      pos 9405
      pos 9415
      pos 10280
      pos 11165
      pos 11378
      pos 11669
      pos 11757
    doc 11
      freq 2
      pos 789
      pos 9024
    doc 12
      freq 3
      pos 3089
      pos 5690
      pos 6878
    doc 13
      freq 1
      pos 6355
    doc 14
      freq 1
      pos 2515
    doc 15
      freq 1
      pos 2918
    doc 17
      freq 3
      pos 1646
      pos 1778
      pos 1816
    skipList 
      level 0
        skipDoc 12
        skipDocFP 560529
        impacts 
          impact 
            freq 1
            norm 104
          impact 
            freq 6
            norm 108
          impact 
            freq 17
            norm 116
        impactsEnd 
  term canonical
    doc 10
      freq 14
      pos 441
      pos 4861
      pos 5116
      pos 5201
      pos 6456
      pos 6744
      pos 6758
      pos 7173
      pos 7206
      pos 12225
      pos 12227
      pos 12241
      pos 12254
      pos 12271
    doc 14
      freq 3
      pos 383
      pos 1098
      pos 1913
  term canonicalized
    doc 10
      freq 1
      pos 5031
  term canonically
    doc 14
      freq 1
      pos 77
  term capabilities
    doc 1
      freq 2
      pos 3992
      pos 6003
    doc 2
      freq 1
      pos 3817
    doc 3
      freq 1
      pos 1972
    doc 5
      freq 1
      pos 3266
    doc 10
      freq 1
      pos 2195
    doc 12
      freq 1
      pos 9206
    doc 16
      freq 2
      pos 1642
      pos 1665
  term capability
    doc 12
      freq 1
      pos 6340
    doc 13
      freq 4
      pos 1919
      pos 1938
      pos 2277
      pos 6821
    doc 16
      freq 6
      pos 510
      pos 526
      pos 1450
      pos 1534
      pos 1672
      pos 1678
  term capabl
    doc 1
      freq 3
      pos 6386
      pos 6458
      pos 9428
    doc 3
      freq 1
      pos 5548
    doc 6
      freq 1
      pos 707
    doc 10
      freq 7
      pos 2150
      pos 4537
      pos 9022
      pos 9696
      pos 12926
      pos 12947
      pos 13004
    doc 12
      freq 1
      pos 1456
    doc 13
      freq 1
      pos 1601
    doc 15
      freq 1
      pos 2406
  term capacity
    doc 12
      freq 1
      pos 9332
    doc 13
      freq 1
      pos 3448
  term capitalization
    doc 10
      freq 1
      pos 5142
  term capitalized
    doc 10
      freq 1
      pos 5130
  term captur
    doc 6
      freq 1
      pos 1091
  term captured
    doc 6
      freq 3
      pos 759
      pos 1076
      pos 2364
    doc 11
      freq 1
      pos 891
  term captures
    doc 0
      freq 2
      pos 4639
      pos 6263
  term capwap
    doc 2
      freq 4
      pos 1757
      pos 1767
      pos 3322
      pos 6034
  term card
    doc 1
      freq 10
      pos 2711
      pos 2717
      pos 4177
      pos 4182
      pos 4254
      pos 4266
      pos 5385
      pos 5577
      pos 7260
      pos 7333
    doc 14
      freq 2
      pos 186
      pos 2224
  term care
    doc 1
      freq 1
      pos 7411
    doc 9
      freq 6
      pos 207
      pos 338
      pos 737
      pos 884
      pos 1209
      pos 1482
    doc 11
      freq 5
      pos 2328
      pos 3719
      pos 5130
      pos 7955
      pos 7981
    doc 12
      freq 1
      pos 4777
    doc 14
      freq 1
      pos 2483
  term careful
    doc 4
      freq 1
      pos 4530
    doc 18
      freq 1
      pos 2051
  term carefully
    doc 7
      freq 1
      pos 247
    doc 9
      freq 1
      pos 1041
    doc 11
      freq 1
      pos 9329
    doc 13
      freq 1
      pos 4657
  term carelessly
    doc 12
      freq 1
      pos 8205
  term carling
    doc 3
      freq 1
      pos 4875
  term carlson
    doc 2
      freq 1
      pos 3270
  term carlucc
    doc 6
      freq 1
      pos 3108
  term carney
    doc 12
      freq 1
      pos 7184
    doc 15
      freq 1
      pos 3950
  term carousel
    doc 13
      freq 2
      pos 2343
      pos 4128
  term carouselled
    doc 13
      freq 2
      pos 2094
      pos 2120
  term carpenter
    doc 2
      freq 1
      pos 6353
    doc 12
      freq 2
      pos 7142
      pos 7319
  term carrar
    doc 5
      freq 3
      pos 4165
      pos 4215
      pos 4360
  term carriag
    doc 11
      freq 1
      pos 915
    doc 13
      freq 1
      pos 5195
  term carried
    doc 0
      freq 1
      pos 11973
    doc 1
      freq 2
      pos 1295
      pos 3755
    doc 2
      freq 1
      pos 1442
    doc 3
      freq 4
      pos 357
      pos 3185
      pos 3329
      pos 3392
    doc 10
      freq 1
      pos 9095
    doc 13
      freq 1
      pos 937
  term carrier
    doc 2
      freq 1
      pos 2599
    doc 3
      freq 2
      pos 4430
      pos 4474
  term carries
    doc 1
      freq 1
      pos 1988
    doc 13
      freq 1
      pos 5618
  term carry
    doc 1
      freq 2
      pos 941
      pos 3480
    doc 3
      freq 2
      pos 107
      pos 3866
    doc 4
      freq 1
      pos 4767
    doc 5
      freq 1
      pos 3454
    doc 6
      freq 1
      pos 2089
    doc 8
      freq 1
      pos 1691
    doc 13
      freq 1
      pos 5325
    doc 15
      freq 7
      pos 936
      pos 1514
      pos 1627
      pos 1652
      pos 2334
      pos 3324
      pos 3714
    skipList 
      level 0
        skipDoc 15
        skipDocFP 565926
        impacts 
          impact 
            freq 1
            norm 97
          impact 
            freq 7
            norm 104
        impactsEnd 
  term carrying
    doc 1
      freq 1
      pos 4393
    doc 3
      freq 1
      pos 373
    doc 5
      freq 1
      pos 2028
    doc 6
      freq 5
      pos 266
      pos 552
      pos 837
      pos 2066
      pos 2747
    doc 13
      freq 2
      pos 3635
      pos 4455
    doc 17
      freq 1
      pos 132
  term cas
    doc 8
      freq 1
      pos 779
    doc 17
      freq 2
      pos 1781
      pos 1828
  term case
    doc 0
      freq 3
      pos 6549
      pos 16293
      pos 17173
    doc 1
      freq 7
      pos 3847
      pos 4890
      pos 6350
      pos 6848
      pos 6888
      pos 7367
      pos 8430
    doc 2
      freq 3
      pos 635
      pos 2065
      pos 4532
    doc 3
      freq 4
      pos 674
      pos 2654
      pos 2955
      pos 3515
    doc 4
      freq 8
      pos 1556
      pos 1745
      pos 1780
      pos 1989
      pos 2493
      pos 2546
      pos 3917
      pos 5805
    doc 6
      freq 5
      pos 603
      pos 619
      pos 1065
      pos 1537
      pos 2104
    doc 7
      freq 3
      pos 1150
      pos 1214
      pos 1403
    doc 10
      freq 12
      pos 1444
      pos 1796
      pos 1937
      pos 2838
      pos 2892
      pos 3507
      pos 5070
      pos 5108
      pos 7200
      pos 7512
      pos 9543
      pos 10588
    doc 11
      freq 3
      pos 1316
      pos 3238
      pos 4856
    doc 12
      freq 18
      pos 1021
      pos 1508
      pos 2209
      pos 2658
      pos 2868
      pos 2984
      pos 3664
      pos 3756
      pos 3823
      pos 5286
      pos 6221
      pos 6286
      pos 6300
      pos 6405
      pos 6448
      pos 6477
      pos 8066
      pos 8877
    doc 13
      freq 7
      pos 1087
      pos 2038
      pos 2069
      pos 2310
      pos 2446
      pos 3078
      pos 4837
    doc 14
      freq 9
      pos 176
      pos 1879
      pos 1891
      pos 1903
      pos 2438
      pos 2964
      pos 4155
      pos 4884
      pos 5138
    doc 15
      freq 8
      pos 1617
      pos 1925
      pos 2072
      pos 2117
      pos 2991
      pos 2997
      pos 3391
      pos 3480
    doc 16
      freq 1
      pos 313
    skipList 
      level 0
        skipDoc 10
        skipDocFP 567003
        impacts 
          impact 
            freq 3
            norm 100
          impact 
            freq 5
            norm 101
          impact 
            freq 8
            norm 108
          impact 
            freq 12
            norm 116
        impactsEnd 
  term cases
    doc 1
      freq 1
      pos 3234
    doc 2
      freq 3
      pos 2211
      pos 6131
      pos 6211
    doc 3
      freq 3
      pos 2348
      pos 3570
      pos 4021
    doc 4
      freq 4
      pos 1470
      pos 1523
      pos 2468
      pos 5751
    doc 7
      freq 2
      pos 1246
      pos 1273
    doc 10
      freq 9
      pos 813
      pos 2793
      pos 2953
      pos 3585
      pos 7422
      pos 7686
      pos 8818
      pos 10350
      pos 10453
    doc 12
      freq 14
      pos 994
      pos 1648
      pos 1821
      pos 2079
      pos 2109
      pos 2390
      pos 2473
      pos 2763
      pos 3618
      pos 5195
      pos 6164
      pos 6355
      pos 8097
      pos 8731
    doc 13
      freq 15
      pos 162
      pos 170
      pos 200
      pos 2003
      pos 2010
      pos 2265
      pos 2404
      pos 2682
      pos 2732
      pos 2745
      pos 4504
      pos 4510
      pos 4532
      pos 4704
      pos 5126
    doc 15
      freq 6
      pos 1287
      pos 1917
      pos 1966
      pos 2019
      pos 2124
      pos 3024
    skipList 
      level 0
        skipDoc 13
        skipDocFP 569051
        impacts 
          impact 
            freq 2
            norm 100
          impact 
            freq 3
            norm 107
          impact 
            freq 4
            norm 108
          impact 
            freq 15
            norm 109
        impactsEnd 
  term casner
    doc 6
      freq 1
      pos 3065
  term castagnol
    doc 0
      freq 1
      pos 15914
  term castr
    doc 12
      freq 1
      pos 7358
  term cat
    doc 16
      freq 3
      pos 1478
      pos 1481
      pos 1483
  term catalog
    doc 11
      freq 1
      pos 670
  term categories
    doc 7
      freq 2
      pos 1287
      pos 1675
  term category
    doc 0
      freq 1
      pos 12
    doc 1
      freq 1
      pos 12
    doc 2
      freq 1
      pos 13
    doc 3
      freq 1
      pos 12
    doc 4
      freq 1
      pos 18
    doc 5
      freq 1
      pos 11
    doc 6
      freq 1
      pos 11
    doc 7
      freq 2
      pos 12
      pos 1344
    doc 8
      freq 1
      pos 16
    doc 9
      freq 1
      pos 12
    doc 10
      freq 1
      pos 10
    doc 11
      freq 1
      pos 12
    doc 12
      freq 1
      pos 10
    doc 13
      freq 1
      pos 11
    doc 14
      freq 1
      pos 11
    doc 15
      freq 1
      pos 12
    doc 16
      freq 1
      pos 16
    doc 17
      freq 1
      pos 10
    doc 18
      freq 1
      pos 16
    skipList 
      level 0
        skipDoc 7
        skipDocFP 570838
        impacts 
          impact 
            freq 2
            norm 100
        impactsEnd 
        skipDoc 15
        skipDocFP 571141
        impacts 
          impact 
            freq 1
            norm 95
        impactsEnd 
  term catenat
    doc 16
      freq 37
      pos 24
      pos 88
      pos 136
      pos 170
      pos 177
      pos 227
      pos 283
      pos 308
      pos 509
      pos 518
      pos 536
      pos 579
      pos 721
      pos 911
      pos 1316
      pos 1476
      pos 1535
      pos 1571
      pos 1601
      pos 1670
      pos 1690
      pos 1749
      pos 1779
      pos 1847
      pos 1858
      pos 1870
      pos 1940
      pos 2116
      pos 2128
      pos 2160
      pos 2253
      pos 2290
      pos 2308
      pos 2463
      pos 2515
      pos 2644
      pos 2684
  term catenated
    doc 16
      freq 4
      pos 813
      pos 1067
      pos 1095
      pos 1110
  term catenates
    doc 16
      freq 1
      pos 276
  term catenating
    doc 16
      freq 1
      pos 503
  term cater
    doc 15
      freq 1
      pos 2825
  term cause
    doc 1
      freq 3
      pos 1233
      pos 7009
      pos 7034
    doc 3
      freq 2
      pos 3457
      pos 5340
    doc 4
      freq 5
      pos 922
      pos 4140
      pos 4188
      pos 4412
      pos 4545
    doc 6
      freq 1
      pos 2418
    doc 10
      freq 6
      pos 3235
      pos 3475
      pos 5675
      pos 8874
      pos 8927
      pos 9496
    doc 11
      freq 1
      pos 9350
    doc 12
      freq 1
      pos 8347
    doc 15
      freq 1
      pos 2849
    doc 16
      freq 1
      pos 804
    skipList 
      level 0
        skipDoc 15
        skipDocFP 572705
        impacts 
          impact 
            freq 1
            norm 101
          impact 
            freq 2
            norm 107
          impact 
            freq 5
            norm 108
          impact 
            freq 6
            norm 116
        impactsEnd 
  term caused
    doc 0
      freq 1
      pos 16536
    doc 4
      freq 3
      pos 1403
      pos 1451
      pos 6024
    doc 11
      freq 1
      pos 700
    doc 16
      freq 1
      pos 1303
  term causes
    doc 12
      freq 2
      pos 9087
      pos 9111
  term causing
    doc 4
      freq 1
      pos 4465
    doc 6
      freq 1
      pos 2411
    doc 12
      freq 1
      pos 9000
  term caution
    doc 6
      freq 1
      pos 160
  term caveat
    doc 10
      freq 1
      pos 6042
  term cbc
    doc 7
      freq 2
      pos 1140
      pos 2729
  term ccp
    doc 7
      freq 1
      pos 2822
  term cd
    doc 2
      freq 1
      pos 2607
    doc 3
      freq 2
      pos 4438
      pos 4482
  term ce
    doc 1
      freq 1
      pos 8148
    doc 3
      freq 11
      pos 235
      pos 509
      pos 531
      pos 1060
      pos 2695
      pos 2837
      pos 2855
      pos 3174
      pos 3195
      pos 3858
      pos 5187
  term ce1
    doc 1
      freq 1
      pos 1033
    doc 3
      freq 1
      pos 608
  term ce2
    doc 1
      freq 1
      pos 1034
    doc 3
      freq 1
      pos 609
  term cell
    doc 8
      freq 5
      pos 647
      pos 679
      pos 688
      pos 702
      pos 711
  term cells
    doc 8
      freq 1
      pos 1026
  term cellular
    doc 13
      freq 2
      pos 911
      pos 3168
  term center
    doc 1
      freq 2
      pos 9256
      pos 9272
    doc 3
      freq 1
      pos 4786
    doc 9
      freq 2
      pos 11
      pos 1769
    doc 13
      freq 2
      pos 7011
      pos 7027
  term cep
    doc 1
      freq 8
      pos 560
      pos 669
      pos 2361
      pos 2362
      pos 2366
      pos 7852
      pos 8974
      pos 8992
    doc 8
      freq 10
      pos 672
      pos 734
      pos 1040
      pos 1044
      pos 1048
      pos 1050
      pos 1059
      pos 1063
      pos 1864
      pos 1882
  term cer
    doc 10
      freq 1
      pos 12313
  term cert
    doc 10
      freq 2
      pos 5636
      pos 12340
  term certain
    doc 0
      freq 1
      pos 16561
    doc 1
      freq 1
      pos 7431
    doc 9
      freq 1
      pos 431
    doc 10
      freq 3
      pos 4865
      pos 8697
      pos 10715
    doc 12
      freq 2
      pos 1680
      pos 4273
    doc 13
      freq 2
      pos 6072
      pos 6352
    doc 15
      freq 1
      pos 924
  term certainly
    doc 11
      freq 1
      pos 5912
    doc 15
      freq 1
      pos 3334
  term certificat
    doc 5
      freq 1
      pos 844
    doc 7
      freq 2
      pos 819
      pos 2229
    doc 10
      freq 59
      pos 162
      pos 333
      pos 1930
      pos 2013
      pos 2142
      pos 2188
      pos 3280
      pos 3349
      pos 3932
      pos 3955
      pos 3969
      pos 4003
      pos 4021
      pos 4069
      pos 4104
      pos 4120
      pos 4137
      pos 4149
      pos 4297
      pos 5419
      pos 5585
      pos 5695
      pos 6076
      pos 6135
      pos 6146
      pos 6195
      pos 6247
      pos 6286
      pos 6591
      pos 6723
      pos 6738
      pos 6769
      pos 6823
      pos 6878
      pos 6915
      pos 7307
      pos 7877
      pos 10056
      pos 10406
      pos 10559
      pos 10643
      pos 10752
      pos 10848
      pos 10875
      pos 10889
      pos 10904
      pos 10914
      pos 10950
      pos 10984
      pos 11734
      pos 11760
      pos 11774
      pos 11783
      pos 11794
      pos 11830
      pos 12303
      pos 12315
      pos 13242
      pos 13244
    doc 17
      freq 20
      pos 19
      pos 88
      pos 95
      pos 104
      pos 169
      pos 172
      pos 207
      pos 215
      pos 231
      pos 301
      pos 451
      pos 679
      pos 1074
      pos 1202
      pos 1259
      pos 1448
      pos 1822
      pos 2062
      pos 2064
      pos 2082
  term certificates
    doc 10
      freq 23
      pos 555
      pos 1639
      pos 1657
      pos 1741
      pos 3948
      pos 3980
      pos 4039
      pos 6039
      pos 6046
      pos 6068
      pos 6071
      pos 6083
      pos 6115
      pos 6119
      pos 10435
      pos 10829
      pos 10853
      pos 10872
      pos 10893
      pos 10943
      pos 10964
      pos 12918
      pos 12939
    doc 17
      freq 1
      pos 255
  term certification
    doc 7
      freq 2
      pos 848
      pos 2258
    doc 10
      freq 1
      pos 4090
    doc 17
      freq 1
      pos 1020
  term ces
    doc 3
      freq 2
      pos 680
      pos 711
  term cesopsn
    doc 8
      freq 6
      pos 766
      pos 769
      pos 776
      pos 780
      pos 2009
      pos 2032
  term cf7wrq9r4kv7xijkxodvccd
    doc 10
      freq 1
      pos 6837
  term cfb0zmq26dl3g7tqnru7pih0q
    doc 11
      freq 1
      pos 10373
  term cfiaiiwuhdcfsep59juxx
    doc 11
      freq 1
      pos 9958
  term cga
    doc 12
      freq 2
      pos 5926
      pos 7550
  term cgas
    doc 12
      freq 3
      pos 5871
      pos 5881
      pos 5911
  term ch
    doc 7
      freq 1
      pos 2907
  term chain
    doc 5
      freq 7
      pos 1230
      pos 1253
      pos 1284
      pos 1443
      pos 1461
      pos 1964
      pos 3691
    doc 10
      freq 2
      pos 1383
      pos 4083
    doc 12
      freq 1
      pos 3584
    doc 18
      freq 1
      pos 141
  term chaining
    doc 5
      freq 2
      pos 149
      pos 484
  term chair
    doc 2
      freq 14
      pos 419
      pos 447
      pos 667
      pos 687
      pos 839
      pos 886
      pos 892
      pos 1455
      pos 3767
      pos 4282
      pos 4565
      pos 4737
      pos 4802
      pos 5211
    doc 11
      freq 2
      pos 1451
      pos 1458
  term chairs
    doc 2
      freq 4
      pos 442
      pos 864
      pos 940
      pos 3573
  term challeng
    doc 10
      freq 5
      pos 1861
      pos 2586
      pos 2616
      pos 2668
      pos 10077
    doc 11
      freq 3
      pos 7957
      pos 7983
      pos 7996
  term challenged
    doc 10
      freq 1
      pos 5863
  term challenges
    doc 13
      freq 1
      pos 6929
  term challenging
    doc 2
      freq 2
      pos 1980
      pos 4953
    doc 13
      freq 1
      pos 6713
  term chan
    doc 0
      freq 1
      pos 16997
  term chanc
    doc 0
      freq 1
      pos 12977
    doc 10
      freq 1
      pos 9170
  term chang
    doc 0
      freq 5
      pos 5349
      pos 7914
      pos 16207
      pos 16790
      pos 16878
    doc 1
      freq 3
      pos 2804
      pos 2833
      pos 5402
    doc 2
      freq 2
      pos 1348
      pos 5917
    doc 3
      freq 3
      pos 5066
      pos 5075
      pos 5173
    doc 4
      freq 3
      pos 1320
      pos 1330
      pos 4239
    doc 10
      freq 3
      pos 4328
      pos 5653
      pos 9151
    doc 13
      freq 9
      pos 830
      pos 852
      pos 2509
      pos 3478
      pos 3579
      pos 4714
      pos 4859
      pos 4913
      pos 4932
    doc 16
      freq 1
      pos 821
    doc 18
      freq 1
      pos 702
    skipList 
      level 0
        skipDoc 16
        skipDocFP 579826
        impacts 
          impact 
            freq 1
            norm 99
          impact 
            freq 3
            norm 107
          impact 
            freq 9
            norm 109
        impactsEnd 
  term changed
    doc 0
      freq 3
      pos 2173
      pos 8229
      pos 11998
    doc 4
      freq 2
      pos 5839
      pos 5939
    doc 12
      freq 1
      pos 5917
    doc 13
      freq 2
      pos 814
      pos 4743
    doc 16
      freq 1
      pos 1897
  term changes
    doc 0
      freq 5
      pos 7664
      pos 14214
      pos 16062
      pos 16077
      pos 16396
    doc 1
      freq 2
      pos 813
      pos 5919
    doc 2
      freq 6
      pos 1144
      pos 5234
      pos 5239
      pos 5550
      pos 5980
      pos 6268
    doc 4
      freq 6
      pos 275
      pos 305
      pos 4328
      pos 5540
      pos 5546
      pos 5765
    doc 7
      freq 1
      pos 2877
    doc 10
      freq 2
      pos 9989
      pos 11448
    doc 13
      freq 8
      pos 699
      pos 3011
      pos 3040
      pos 3088
      pos 3545
      pos 3571
      pos 4179
      pos 4870
    doc 14
      freq 1
      pos 2475
    doc 18
      freq 1
      pos 577
    skipList 
      level 0
        skipDoc 14
        skipDocFP 581051
        impacts 
          impact 
            freq 1
            norm 100
          impact 
            freq 6
            norm 108
          impact 
            freq 8
            norm 109
        impactsEnd 
  term changesinadjacencystat
    doc 0
      freq 2
      pos 7922
      pos 7959
  term changing
    doc 0
      freq 2
      pos 16249
      pos 16415
    doc 2
      freq 2
      pos 5836
      pos 5864
    doc 9
      freq 1
      pos 1351
    doc 10
      freq 3
      pos 8684
      pos 9467
      pos 9726
    doc 13
      freq 2
      pos 4592
      pos 4602
  term changming
    doc 15
      freq 1
      pos 3853
  term channel
    doc 8
      freq 4
      pos 161
      pos 1638
      pos 1647
      pos 1656
    doc 10
      freq 1
      pos 4406
    doc 12
      freq 1
      pos 4617
    doc 13
      freq 2
      pos 524
      pos 2248
  term channels
    doc 2
      freq 1
      pos 3664
    doc 13
      freq 8
      pos 2202
      pos 2213
      pos 2236
      pos 2256
      pos 2262
      pos 2396
      pos 4554
      pos 4606
  term chapman
    doc 0
      freq 1
      pos 15916
  term char
    doc 16
      freq 1
      pos 1532
  term character
    doc 1
      freq 1
      pos 9171
    doc 7
      freq 2
      pos 964
      pos 2408
    doc 8
      freq 1
      pos 1752
    doc 10
      freq 1
      pos 4907
    doc 11
      freq 9
      pos 1315
      pos 1623
      pos 1682
      pos 1777
      pos 1783
      pos 2143
      pos 2156
      pos 2429
      pos 4098
    doc 14
      freq 4
      pos 2196
      pos 2206
      pos 2256
      pos 2593
    doc 18
      freq 1
      pos 1299
  term characteristic
    doc 13
      freq 1
      pos 5076
  term characteristics
    doc 1
      freq 2
      pos 621
      pos 689
    doc 3
      freq 1
      pos 1320
    doc 11
      freq 2
      pos 708
      pos 6851
    doc 12
      freq 1
      pos 2344
  term characteriz
    doc 6
      freq 2
      pos 693
      pos 2625
  term characterized
    doc 6
      freq 3
      pos 2245
      pos 2259
      pos 2638
  term characterizes
    doc 5
      freq 1
      pos 1413
    doc 6
      freq 1
      pos 805
  term characterizing
    doc 6
      freq 3
      pos 262
      pos 512
      pos 754
  term characters
    doc 8
      freq 4
      pos 925
      pos 1250
      pos 1431
      pos 1572
    doc 10
      freq 2
      pos 5198
      pos 5284
    doc 11
      freq 32
      pos 114
      pos 147
      pos 313
      pos 354
      pos 888
      pos 998
      pos 1016
      pos 1218
      pos 1585
      pos 1593
      pos 1614
      pos 1654
      pos 1663
      pos 1708
      pos 1729
      pos 1753
      pos 1765
      pos 1812
      pos 1842
      pos 2062
      pos 2072
      pos 3715
      pos 3965
      pos 5561
      pos 5591
      pos 5609
      pos 5710
      pos 5721
      pos 5757
      pos 5775
      pos 6491
      pos 6514
    doc 14
      freq 1
      pos 2286
    doc 17
      freq 1
      pos 1215
  term charg
    doc 2
      freq 1
      pos 744
  term charged
    doc 2
      freq 1
      pos 1907
  term charges
    doc 13
      freq 1
      pos 2139
  term charl
    doc 4
      freq 1
      pos 5480
  term charles
    doc 9
      freq 1
      pos 1764
  term charles.perkins
    doc 9
      freq 1
      pos 1789
  term charset
    doc 1
      freq 1
      pos 6279
    doc 16
      freq 2
      pos 2032
      pos 2212
  term charter
    doc 2
      freq 5
      pos 1089
      pos 1123
      pos 1759
      pos 3776
      pos 5791
  term charter.html
    doc 0
      freq 1
      pos 1101
  term chartered
    doc 2
      freq 3
      pos 5635
      pos 5929
      pos 6044
  term chartering
    doc 2
      freq 1
      pos 1208
  term charters
    doc 2
      freq 2
      pos 992
      pos 1033
  term chcjx5
    doc 10
      freq 1
      pos 12661
  term check
    doc 3
      freq 4
      pos 1365
      pos 3106
      pos 3767
      pos 4653
    doc 8
      freq 1
      pos 1856
    doc 10
      freq 3
      pos 2297
      pos 3013
      pos 3053
    doc 12
      freq 6
      pos 3421
      pos 4994
      pos 5103
      pos 5125
      pos 5499
      pos 6951
    doc 13
      freq 1
      pos 3460
  term checking
    doc 10
      freq 1
      pos 4075
    doc 12
      freq 1
      pos 8188
  term checks
    doc 4
      freq 1
      pos 4627
    doc 12
      freq 1
      pos 5142
    doc 14
      freq 1
      pos 1352
  term checksum
    doc 0
      freq 4
      pos 7337
      pos 11911
      pos 12008
      pos 12208
    doc 4
      freq 19
      pos 173
      pos 624
      pos 665
      pos 1086
      pos 1254
      pos 1257
      pos 1317
      pos 1334
      pos 1336
      pos 2130
      pos 2796
      pos 3041
      pos 3277
      pos 3584
      pos 3755
      pos 4264
      pos 4281
      pos 4287
      pos 5770
  term cheers
    doc 16
      freq 1
      pos 2054
  term chicago.example.com
    doc 10
      freq 2
      pos 7450
      pos 7475
  term child.example.com
    doc 12
      freq 2
      pos 2848
      pos 8413
  term chiment
    doc 6
      freq 1
      pos 3013
  term chiquoin
    doc 6
      freq 1
      pos 3119
  term choic
    doc 4
      freq 1
      pos 1241
    doc 10
      freq 1
      pos 5091
    doc 13
      freq 1
      pos 105
    doc 14
      freq 2
      pos 180
      pos 2005
    doc 15
      freq 5
      pos 574
      pos 718
      pos 1412
      pos 3034
      pos 3303
    doc 18
      freq 1
      pos 1861
  term choices
    doc 15
      freq 1
      pos 3511
    doc 18
      freq 1
      pos 1863
  term choos
    doc 4
      freq 1
      pos 1098
    doc 11
      freq 4
      pos 4617
      pos 4820
      pos 5287
      pos 5877
    doc 13
      freq 1
      pos 6277
    doc 15
      freq 4
      pos 946
      pos 996
      pos 1359
      pos 1566
  term chooses
    doc 12
      freq 1
      pos 4749
    doc 18
      freq 1
      pos 1822
  term choosing
    doc 10
      freq 2
      pos 8889
      pos 9842
    doc 11
      freq 4
      pos 3297
      pos 6314
      pos 6841
      pos 8003
    doc 13
      freq 1
      pos 4282
    doc 15
      freq 2
      pos 1007
      pos 1798
    doc 18
      freq 1
      pos 1986
  term chose
    doc 7
      freq 1
      pos 1583
  term chosen
    doc 3
      freq 1
      pos 2221
    doc 4
      freq 1
      pos 1195
    doc 6
      freq 2
      pos 146
      pos 1415
    doc 18
      freq 3
      pos 1725
      pos 1747
      pos 1817
  term chown
    doc 12
      freq 1
      pos 7682
    doc 15
      freq 16
      pos 4
      pos 186
      pos 297
      pos 627
      pos 1017
      pos 1385
      pos 1745
      pos 2140
      pos 2586
      pos 2998
      pos 3399
      pos 3794
      pos 4000
      pos 4017
      pos 4063
      pos 4396
  term chris
    doc 0
      freq 2
      pos 1166
      pos 15849
    doc 1
      freq 1
      pos 9338
    doc 3
      freq 1
      pos 4841
  term chris.liljenstolp
    doc 1
      freq 1
      pos 9351
    doc 3
      freq 1
      pos 4854
  term chris_s_francis
    doc 17
      freq 1
      pos 2382
  term christian
    doc 0
      freq 1
      pos 15944
    doc 15
      freq 1
      pos 4046
  term christopher
    doc 3
      freq 1
      pos 4900
    doc 17
      freq 1
      pos 2367
  term christopher.flores
    doc 3
      freq 1
      pos 4913
  term chronological
    doc 4
      freq 1
      pos 5506
  term cidr
    doc 7
      freq 4
      pos 1421
      pos 2447
      pos 2457
      pos 2464
  term cipx
    doc 7
      freq 2
      pos 1011
      pos 2498
  term circindex
    doc 0
      freq 1
      pos 5224
  term circuit
    doc 0
      freq 72
      pos 617
      pos 619
      pos 699
      pos 1300
      pos 1315
      pos 1323
      pos 1979
      pos 5364
      pos 5382
      pos 5392
      pos 5396
      pos 5446
      pos 5528
      pos 5610
      pos 5638
      pos 5660
      pos 5678
      pos 5692
      pos 5743
      pos 5814
      pos 5847
      pos 5877
      pos 5881
      pos 5992
      pos 6003
      pos 6044
      pos 6055
      pos 6145
      pos 6167
      pos 6200
      pos 6230
      pos 6258
      pos 6269
      pos 6315
      pos 6415
      pos 6457
      pos 6517
      pos 6535
      pos 6546
      pos 6587
      pos 6624
      pos 6641
      pos 6664
      pos 6686
      pos 6696
      pos 6700
      pos 6739
      pos 6893
      pos 7742
      pos 7760
      pos 7786
      pos 7855
      pos 7919
      pos 7944
      pos 7982
      pos 8027
      pos 8232
      pos 8238
      pos 8291
      pos 8320
      pos 8948
      pos 9159
      pos 10100
      pos 10487
      pos 11517
      pos 11581
      pos 12349
      pos 13106
      pos 13302
      pos 13885
      pos 14279
      pos 15540
    doc 1
      freq 23
      pos 158
      pos 573
      pos 586
      pos 620
      pos 664
      pos 688
      pos 1020
      pos 1025
      pos 1692
      pos 2028
      pos 2781
      pos 3988
      pos 4485
      pos 4509
      pos 4837
      pos 4994
      pos 5367
      pos 5999
      pos 8021
      pos 8465
      pos 8474
      pos 8788
      pos 8987
    doc 3
      freq 11
      pos 624
      pos 627
      pos 810
      pos 1436
      pos 1906
      pos 1968
      pos 2515
      pos 2570
      pos 2761
      pos 2790
      pos 4672
    doc 8
      freq 7
      pos 667
      pos 730
      pos 1600
      pos 1608
      pos 1821
      pos 1877
      pos 2025
  term circuits
    doc 0
      freq 12
      pos 5421
      pos 5976
      pos 6028
      pos 6095
      pos 6251
      pos 6288
      pos 6527
      pos 6561
      pos 6880
      pos 8481
      pos 8543
      pos 8600
    doc 1
      freq 2
      pos 8444
      pos 8846
    doc 3
      freq 1
      pos 1763
    doc 7
      freq 2
      pos 2517
      pos 2702
  term circular
    doc 3
      freq 1
      pos 3752
  term circulat
    doc 2
      freq 1
      pos 2009
  term circumstances
    doc 12
      freq 1
      pos 3597
  term circumvent
    doc 10
      freq 1
      pos 818
  term circumvented
    doc 10
      freq 1
      pos 876
  term cisco
    doc 1
      freq 6
      pos 15
      pos 9202
      pos 9233
      pos 9382
      pos 9507
      pos 9560
    doc 3
      freq 4
      pos 15
      pos 4768
      pos 5872
      pos 5925
    doc 4
      freq 2
      pos 16
      pos 6060
    doc 6
      freq 2
      pos 15
      pos 3200
    doc 7
      freq 4
      pos 9
      pos 16
      pos 2900
      pos 2921
    doc 8
      freq 2
      pos 9
      pos 2131
    doc 10
      freq 2
      pos 15
      pos 13431
    doc 11
      freq 3
      pos 23
      pos 9612
      pos 10566
    skipList 
      level 0
        skipDoc 11
        skipDocFP 591869
        impacts 
          impact 
            freq 2
            norm 97
          impact 
            freq 4
            norm 100
          impact 
            freq 6
            norm 113
        impactsEnd 
  term cisco.com
    doc 1
      freq 5
      pos 9216
      pos 9249
      pos 9393
      pos 9521
      pos 9571
    doc 3
      freq 3
      pos 4779
      pos 5886
      pos 5936
    doc 6
      freq 1
      pos 3217
    doc 7
      freq 1
      pos 2917
    doc 8
      freq 1
      pos 2145
    doc 10
      freq 1
      pos 13453
    doc 11
      freq 1
      pos 10581
  term citation
    doc 8
      freq 4
      pos 601
      pos 979
      pos 1273
      pos 1468
  term city
    doc 3
      freq 1
      pos 4803
  term ck1ukixlb3prq7fmyqzmt23pon
    doc 11
      freq 1
      pos 9884
  term ckgy5vjkslf5e8v0ev8mq3bwhpctyqv9mvean9
    doc 10
      freq 1
      pos 12766
  term ckt
    doc 11
      freq 1
      pos 9938
  term claim
    doc 0
      freq 1
      pos 14784
    doc 10
      freq 6
      pos 1981
      pos 2538
      pos 4442
      pos 9314
      pos 9664
      pos 9836
  term claimed
    doc 0
      freq 1
      pos 17355
    doc 1
      freq 1
      pos 9736
    doc 2
      freq 1
      pos 6533
    doc 3
      freq 1
      pos 6085
    doc 4
      freq 1
      pos 6240
    doc 5
      freq 1
      pos 4570
    doc 6
      freq 1
      pos 3370
    doc 7
      freq 1
      pos 3075
    doc 8
      freq 1
      pos 2292
    doc 9
      freq 3
      pos 206
      pos 337
      pos 1937
    doc 10
      freq 1
      pos 13598
    doc 11
      freq 1
      pos 10759
    doc 12
      freq 1
      pos 9609
    doc 13
      freq 1
      pos 7224
    doc 14
      freq 1
      pos 5690
    doc 15
      freq 1
      pos 4209
    doc 16
      freq 1
      pos 2820
    doc 17
      freq 1
      pos 2544
    doc 18
      freq 1
      pos 2332
    skipList 
      level 0
        skipDoc 7
        skipDocFP 593608
        impacts 
          impact 
            freq 1
            norm 100
        impactsEnd 
        skipDoc 15
        skipDocFP 593913
        impacts 
          impact 
            freq 3
            norm 95
        impactsEnd 
  term claims
    doc 9
      freq 1
      pos 1551
    doc 10
      freq 1
      pos 9820
  term clara
    doc 3
      freq 1
      pos 4894
  term clarification
    doc 2
      freq 1
      pos 2085
    doc 14
      freq 1
      pos 2011
  term clarifications
    doc 2
      freq 4
      pos 4978
      pos 5061
      pos 5296
      pos 5802
    doc 12
      freq 1
      pos 7040
    doc 14
      freq 1
      pos 5396
  term clarified
    doc 4
      freq 1
      pos 5776
    doc 15
      freq 1
      pos 3250
  term clarifying
    doc 12
      freq 1
      pos 6789
  term clarity
    doc 2
      freq 2
      pos 2055
      pos 5136
  term clark
    doc 6
      freq 14
      pos 14
      pos 283
      pos 736
      pos 1126
      pos 1607
      pos 2022
      pos 2336
      pos 2752
      pos 2969
      pos 3029
      pos 3050
      pos 3199
      pos 3219
      pos 3558
  term class
    doc 0
      freq 1
      pos 16213
    doc 3
      freq 1
      pos 3956
    doc 17
      freq 1
      pos 322
  term classes
    doc 2
      freq 2
      pos 3005
      pos 3399
    doc 3
      freq 1
      pos 5675
    doc 4
      freq 1
      pos 689
    doc 7
      freq 1
      pos 1182
    doc 12
      freq 3
      pos 1621
      pos 1676
      pos 1908
    doc 13
      freq 1
      pos 2063
  term classification
    doc 2
      freq 1
      pos 4706
    doc 3
      freq 2
      pos 5456
      pos 5500
    doc 7
      freq 1
      pos 1662
  term classify
    doc 7
      freq 1
      pos 81
  term classless
    doc 7
      freq 3
      pos 1417
      pos 2443
      pos 2460
  term claus
    doc 0
      freq 3
      pos 14441
      pos 14607
      pos 16107
    doc 2
      freq 1
      pos 3703
    doc 3
      freq 1
      pos 2942
  term clauses
    doc 0
      freq 2
      pos 14417
      pos 14583
    doc 2
      freq 2
      pos 4136
      pos 4143
  term clausthal
    doc 15
      freq 3
      pos 19
      pos 4048
      pos 4054
  term clausthal.d
    doc 15
      freq 1
      pos 4062
  term clayes
    doc 17
      freq 1
      pos 2392
  term clean
    doc 12
      freq 1
      pos 5709
  term cleaned
    doc 12
      freq 1
      pos 5668
  term clear
    doc 3
      freq 1
      pos 5416
    doc 4
      freq 1
      pos 5926
    doc 8
      freq 2
      pos 414
      pos 1588
    doc 10
      freq 1
      pos 7517
    doc 12
      freq 2
      pos 5178
      pos 6685
    doc 13
      freq 2
      pos 1534
      pos 3918
    doc 15
      freq 1
      pos 767
    doc 17
      freq 1
      pos 1833
    skipList 
      level 0
        skipDoc 17
        skipDocFP 596861
        impacts 
          impact 
            freq 2
            norm 97
        impactsEnd 
  term cleared
    doc 0
      freq 1
      pos 12817
    doc 1
      freq 2
      pos 5165
      pos 5178
    doc 3
      freq 1
      pos 5360
  term clearing
    doc 0
      freq 1
      pos 5025
  term clearly
    doc 10
      freq 1
      pos 3606
    doc 11
      freq 1
      pos 655
    doc 17
      freq 1
      pos 1636
  term clears
    doc 0
      freq 1
      pos 5117
  term clerr
    doc 11
      freq 2
      pos 4446
      pos 4468
  term clever
    doc 12
      freq 1
      pos 6658
  term client
    doc 3
      freq 1
      pos 462
    doc 10
      freq 4
      pos 2640
      pos 2644
      pos 3224
      pos 10639
    doc 12
      freq 5
      pos 1024
      pos 2680
      pos 7816
      pos 8836
      pos 9277
    doc 13
      freq 3
      pos 1755
      pos 1918
      pos 1923
    doc 15
      freq 16
      pos 900
      pos 1154
      pos 1168
      pos 1240
      pos 1455
      pos 1458
      pos 1788
      pos 2682
      pos 2743
      pos 2844
      pos 2884
      pos 2917
      pos 3145
      pos 3501
      pos 3532
      pos 3986
    doc 16
      freq 12
      pos 134
      pos 189
      pos 323
      pos 344
      pos 371
      pos 389
      pos 451
      pos 1059
      pos 1142
      pos 1348
      pos 1750
      pos 1767
  term client's
    doc 16
      freq 1
      pos 339
  term clients
    doc 12
      freq 4
      pos 2173
      pos 2452
      pos 7872
      pos 9097
    doc 13
      freq 2
      pos 1739
      pos 3407
    doc 15
      freq 7
      pos 152
      pos 1310
      pos 2575
      pos 2603
      pos 2605
      pos 2966
      pos 3523
    doc 16
      freq 2
      pos 103
      pos 1375
    doc 18
      freq 1
      pos 287
  term cliff
    doc 6
      freq 1
      pos 3149
  term cljsrv2uxpvaa5ywtk6bpafzigt9y5jtlzeizpl8tzctjptni1khqnjqthjz
    doc 11
      freq 1
      pos 10303
  term clns
    doc 0
      freq 3
      pos 16242
      pos 16616
      pos 16628
  term clock
    doc 5
      freq 7
      pos 1122
      pos 1127
      pos 1172
      pos 2174
      pos 2436
      pos 2510
      pos 2541
  term clocks
    doc 5
      freq 1
      pos 1154
  term close
    doc 11
      freq 1
      pos 4431
    doc 12
      freq 1
      pos 5563
    doc 18
      freq 2
      pos 1255
      pos 1851
  term closed
    doc 9
      freq 1
      pos 575
    doc 10
      freq 2
      pos 8115
      pos 8143
    doc 11
      freq 2
      pos 4581
      pos 8311
    doc 13
      freq 1
      pos 6157
  term closest
    doc 18
      freq 1
      pos 1078
  term closing
    doc 3
      freq 1
      pos 1577
  term clouds
    doc 12
      freq 1
      pos 7153
  term cms
    doc 10
      freq 1
      pos 13206
  term cmzx
    doc 11
      freq 1
      pos 10033
  term co
    doc 1
      freq 2
      pos 9517
      pos 9533
    doc 2
      freq 1
      pos 5210
    doc 3
      freq 2
      pos 5882
      pos 5898
    doc 8
      freq 1
      pos 2141
    doc 15
      freq 1
      pos 3634
  term code
    doc 0
      freq 1
      pos 5332
    doc 1
      freq 12
      pos 2346
      pos 4547
      pos 5107
      pos 5110
      pos 5134
      pos 5146
      pos 5307
      pos 5753
      pos 6347
      pos 6900
      pos 6934
      pos 7813
    doc 2
      freq 1
      pos 3612
    doc 4
      freq 44
      pos 249
      pos 623
      pos 646
      pos 938
      pos 977
      pos 1701
      pos 2129
      pos 2167
      pos 2210
      pos 2300
      pos 2355
      pos 2382
      pos 2459
      pos 2504
      pos 2568
      pos 2624
      pos 2650
      pos 2683
      pos 2795
      pos 2833
      pos 3040
      pos 3078
      pos 3097
      pos 3150
      pos 3178
      pos 3276
      pos 3314
      pos 3453
      pos 3481
      pos 3583
      pos 3601
      pos 3754
      pos 3780
      pos 4702
      pos 4751
      pos 4777
      pos 4778
      pos 4862
      pos 5007
      pos 5027
      pos 5076
      pos 5648
      pos 5685
      pos 5910
    doc 5
      freq 1
      pos 147
    doc 8
      freq 3
      pos 406
      pos 418
      pos 1576
    doc 10
      freq 27
      pos 320
      pos 328
      pos 335
      pos 343
      pos 2593
      pos 3095
      pos 11454
      pos 11554
      pos 11562
      pos 11601
      pos 11617
      pos 11627
      pos 11642
      pos 11650
      pos 11696
      pos 11712
      pos 11722
      pos 11736
      pos 11744
      pos 11797
      pos 11813
      pos 11823
      pos 11849
      pos 11857
      pos 11891
      pos 11907
      pos 11917
    doc 11
      freq 4
      pos 383
      pos 4102
      pos 6941
      pos 6947
    doc 12
      freq 1
      pos 8516
    doc 14
      freq 1
      pos 1957
    doc 16
      freq 16
      pos 1198
      pos 1239
      pos 1253
      pos 1288
      pos 1326
      pos 1397
      pos 1454
      pos 1499
      pos 1502
      pos 1505
      pos 1508
      pos 1512
      pos 1554
      pos 1921
      pos 2273
      pos 2495
    skipList 
      level 0
        skipDoc 11
        skipDocFP 600357
        impacts 
          impact 
            freq 3
            norm 97
          impact 
            freq 44
            norm 108
        impactsEnd 
  term codecs
    doc 13
      freq 2
      pos 416
      pos 1627
  term codes
    doc 1
      freq 5
      pos 374
      pos 760
      pos 2341
      pos 7796
      pos 7804
    doc 4
      freq 5
      pos 2457
      pos 2674
      pos 3444
      pos 4813
      pos 5099
    doc 8
      freq 1
      pos 1521
    doc 10
      freq 2
      pos 4512
      pos 4519
    doc 16
      freq 2
      pos 1206
      pos 1228
  term coexist
    doc 16
      freq 1
      pos 287
  term cohen
    doc 1
      freq 1
      pos 8979
    doc 8
      freq 1
      pos 1869
  term coin
    doc 12
      freq 1
      pos 8913
  term coincident
    doc 6
      freq 1
      pos 2402
  term colin
    doc 13
      freq 1
      pos 6971
  term collaborating
    doc 2
      freq 1
      pos 821
  term colleagues
    doc 15
      freq 1
      pos 3885
  term collect
    doc 10
      freq 1
      pos 10113
  term collected
    doc 0
      freq 1
      pos 8383
    doc 16
      freq 1
      pos 2627
  term collection
    doc 0
      freq 1
      pos 1371
    doc 13
      freq 1
      pos 598
  term collections
    doc 0
      freq 8
      pos 15463
      pos 15531
      pos 15577
      pos 15658
      pos 15682
      pos 15710
      pos 15752
      pos 15782
  term collectively
    doc 10
      freq 1
      pos 8333
  term colleg
    doc 0
      freq 2
      pos 1112
      pos 17204
    doc 2
      freq 1
      pos 2868
  term collision
    doc 2
      freq 1
      pos 2604
    doc 3
      freq 2
      pos 4435
      pos 4479
    doc 12
      freq 1
      pos 5742
  term collisions
    doc 17
      freq 2
      pos 1815
      pos 1838
  term colons
    doc 11
      freq 1
      pos 1228
  term columb
    doc 11
      freq 2
      pos 27
      pos 10587
    doc 13
      freq 2
      pos 27
      pos 7063
    doc 18
      freq 1
      pos 2167
  term column
    doc 0
      freq 3
      pos 3640
      pos 4156
      pos 10998
  term com
    doc 7
      freq 1
      pos 2904
    doc 18
      freq 4
      pos 1013
      pos 1016
      pos 1020
      pos 1136
  term combin
    doc 0
      freq 2
      pos 3556
      pos 7883
    doc 13
      freq 1
      pos 5905
    doc 15
      freq 1
      pos 3423
  term combination
    doc 1
      freq 2
      pos 3193
      pos 8066
    doc 4
      freq 1
      pos 4284
    doc 5
      freq 1
      pos 722
    doc 13
      freq 2
      pos 3214
      pos 3830
    doc 16
      freq 2
      pos 115
      pos 248
    doc 17
      freq 1
      pos 1470
  term combinations
    doc 1
      freq 1
      pos 8524
    doc 3
      freq 2
      pos 5110
      pos 5127
  term combined
    doc 1
      freq 1
      pos 3827
    doc 2
      freq 3
      pos 2736
      pos 3581
      pos 4227
    doc 13
      freq 2
      pos 982
      pos 5954
    doc 15
      freq 3
      pos 2988
      pos 3546
      pos 3621
  term combines
    doc 6
      freq 1
      pos 2689
    doc 13
      freq 1
      pos 1379
  term combining
    doc 6
      freq 1
      pos 2156
  term comcast
    doc 12
      freq 2
      pos 9
      pos 9430
  term coming
    doc 13
      freq 4
      pos 230
      pos 3483
      pos 3514
      pos 3554
  term comma
    doc 11
      freq 2
      pos 1238
      pos 1375
  term command
    doc 1
      freq 1
      pos 4285
    doc 7
      freq 1
      pos 2608
    doc 16
      freq 24
      pos 100
      pos 232
      pos 242
      pos 300
      pos 382
      pos 420
      pos 527
      pos 543
      pos 623
      pos 630
      pos 673
      pos 801
      pos 818
      pos 829
      pos 857
      pos 975
      pos 991
      pos 1001
      pos 1177
      pos 1224
      pos 1232
      pos 1300
      pos 1932
      pos 2266
  term commands
    doc 2
      freq 1
      pos 6167
  term commas
    doc 11
      freq 1
      pos 4236
  term comment
    doc 2
      freq 2
      pos 1805
      pos 5377
    doc 12
      freq 1
      pos 7517
  term comments
    doc 0
      freq 2
      pos 8
      pos 15910
    doc 1
      freq 1
      pos 8
    doc 2
      freq 10
      pos 8
      pos 1793
      pos 1822
      pos 4518
      pos 5366
      pos 5426
      pos 5459
      pos 5469
      pos 5541
      pos 6265
    doc 3
      freq 1
      pos 8
    doc 4
      freq 1
      pos 7
    doc 5
      freq 2
      pos 7
      pos 2686
    doc 6
      freq 1
      pos 7
    doc 7
      freq 2
      pos 7
      pos 411
    doc 8
      freq 1
      pos 7
    doc 9
      freq 1
      pos 7
    doc 10
      freq 2
      pos 7
      pos 12138
    doc 11
      freq 2
      pos 8
      pos 9550
    doc 12
      freq 1
      pos 7
    doc 13
      freq 2
      pos 7
      pos 6981
    doc 14
      freq 1
      pos 7
    doc 15
      freq 2
      pos 7
      pos 840
    doc 16
      freq 1
      pos 7
    doc 17
      freq 1
      pos 7
    doc 18
      freq 1
      pos 7
    skipList 
      level 0
        skipDoc 7
        skipDocFP 606436
        impacts 
          impact 
            freq 2
            norm 100
          impact 
            freq 10
            norm 108
        impactsEnd 
        skipDoc 15
        skipDocFP 606897
        impacts 
          impact 
            freq 1
            norm 95
          impact 
            freq 2
            norm 104
        impactsEnd 
  term committe
    doc 2
      freq 5
      pos 373
      pos 453
      pos 1019
      pos 2882
      pos 6301
  term committed
    doc 5
      freq 1
      pos 1467
  term committing
    doc 9
      freq 1
      pos 924
  term common
    doc 0
      freq 1
      pos 14114
    doc 2
      freq 2
      pos 2539
      pos 2595
    doc 3
      freq 1
      pos 3235
    doc 6
      freq 1
      pos 2087
    doc 10
      freq 1
      pos 7538
    doc 12
      freq 1
      pos 7374
    doc 15
      freq 1
      pos 1909
    doc 17
      freq 1
      pos 326
    skipList 
      level 0
        skipDoc 17
        skipDocFP 608008
        impacts 
          impact 
            freq 1
            norm 98
          impact 
            freq 2
            norm 108
        impactsEnd 
  term commonly
    doc 5
      freq 1
      pos 393
    doc 10
      freq 6
      pos 439
      pos 1051
      pos 2164
      pos 7411
      pos 7437
      pos 8558
    doc 11
      freq 1
      pos 7431
    doc 18
      freq 1
      pos 272
  term commonplac
    doc 12
      freq 1
      pos 5981
  term communicat
    doc 2
      freq 1
      pos 6107
    doc 10
      freq 2
      pos 1307
      pos 1815
    doc 13
      freq 2
      pos 3719
      pos 4831
    doc 15
      freq 1
      pos 368
  term communicated
    doc 5
      freq 1
      pos 716
  term communicating
    doc 2
      freq 1
      pos 700
    doc 5
      freq 2
      pos 2142
      pos 3297
    doc 12
      freq 1
      pos 1458
  term communication
    doc 1
      freq 2
      pos 4931
      pos 4974
    doc 4
      freq 2
      pos 2174
      pos 5258
    doc 5
      freq 15
      pos 108
      pos 365
      pos 392
      pos 414
      pos 619
      pos 622
      pos 669
      pos 675
      pos 690
      pos 2939
      pos 3073
      pos 3309
      pos 3332
      pos 3345
      pos 3596
    doc 12
      freq 2
      pos 2700
      pos 3708
    doc 13
      freq 2
      pos 3246
      pos 3316
  term communications
    doc 1
      freq 2
      pos 23
      pos 9527
    doc 2
      freq 8
      pos 120
      pos 339
      pos 398
      pos 573
      pos 603
      pos 713
      pos 6055
      pos 6072
    doc 3
      freq 2
      pos 23
      pos 5892
    doc 5
      freq 1
      pos 213
    doc 6
      freq 2
      pos 3117
      pos 3148
    doc 13
      freq 3
      pos 542
      pos 2276
      pos 4105
    doc 15
      freq 1
      pos 79
  term communities
    doc 7
      freq 1
      pos 2883
  term community
    doc 0
      freq 2
      pos 43
      pos 109
    doc 1
      freq 1
      pos 60
    doc 2
      freq 1
      pos 33
    doc 3
      freq 1
      pos 54
    doc 4
      freq 1
      pos 56
    doc 5
      freq 1
      pos 40
    doc 6
      freq 1
      pos 36
    doc 7
      freq 4
      pos 47
      pos 228
      pos 448
      pos 1157
    doc 8
      freq 1
      pos 44
    doc 9
      freq 1
      pos 42
    doc 10
      freq 1
      pos 45
    doc 11
      freq 1
      pos 49
    doc 12
      freq 1
      pos 39
    doc 13
      freq 1
      pos 48
    doc 14
      freq 1
      pos 36
    doc 15
      freq 3
      pos 47
      pos 1128
      pos 1188
    doc 16
      freq 1
      pos 41
    doc 17
      freq 2
      pos 38
      pos 319
    doc 18
      freq 1
      pos 47
    skipList 
      level 0
        skipDoc 7
        skipDocFP 610269
        impacts 
          impact 
            freq 4
            norm 100
        impactsEnd 
        skipDoc 15
        skipDocFP 610614
        impacts 
          impact 
            freq 1
            norm 95
          impact 
            freq 3
            norm 104
        impactsEnd 
  term compact
    doc 10
      freq 2
      pos 11526
      pos 11533
  term companies
    doc 2
      freq 2
      pos 1184
      pos 3907
  term companion
    doc 1
      freq 1
      pos 195
    doc 10
      freq 1
      pos 2001
  term company
    doc 8
      freq 4
      pos 606
      pos 984
      pos 1278
      pos 1473
  term company.com
    doc 11
      freq 1
      pos 8124
  term compar
    doc 10
      freq 3
      pos 2401
      pos 3062
      pos 10381
  term comparabl
    doc 10
      freq 2
      pos 9123
      pos 10587
    doc 15
      freq 1
      pos 3219
  term compared
    doc 12
      freq 1
      pos 3053
  term compares
    doc 10
      freq 1
      pos 778
  term comparing
    doc 1
      freq 1
      pos 3897
    doc 6
      freq 1
      pos 264
  term comparison
    doc 15
      freq 1
      pos 2928
  term compatibility
    doc 3
      freq 1
      pos 3552
    doc 10
      freq 3
      pos 5926
      pos 7716
      pos 9540
    doc 11
      freq 3
      pos 522
      pos 9144
      pos 9176
  term compatibl
    doc 0
      freq 1
      pos 5755
    doc 10
      freq 1
      pos 7777
    doc 13
      freq 2
      pos 4877
      pos 6313
    doc 18
      freq 1
      pos 708
  term compelling
    doc 10
      freq 1
      pos 1450
  term compensat
    doc 10
      freq 1
      pos 10705
  term complement
    doc 4
      freq 2
      pos 1263
      pos 1267
  term complemented
    doc 15
      freq 1
      pos 119
  term complet
    doc 0
      freq 2
      pos 7118
      pos 11704
    doc 1
      freq 4
      pos 4561
      pos 6810
      pos 6915
      pos 9467
    doc 2
      freq 2
      pos 809
      pos 4643
    doc 4
      freq 2
      pos 3400
      pos 4108
    doc 5
      freq 2
      pos 981
      pos 1098
    doc 12
      freq 4
      pos 8799
      pos 8818
      pos 9018
      pos 9266
    doc 13
      freq 2
      pos 4337
      pos 5431
  term completed
    doc 1
      freq 1
      pos 4916
    doc 2
      freq 1
      pos 4121
    doc 8
      freq 1
      pos 301
    doc 16
      freq 5
      pos 599
      pos 1849
      pos 2095
      pos 2107
      pos 2244
  term completely
    doc 5
      freq 2
      pos 2586
      pos 3755
    doc 7
      freq 1
      pos 1771
    doc 12
      freq 4
      pos 3671
      pos 5247
      pos 5407
      pos 9352
    doc 15
      freq 2
      pos 2349
      pos 3342
  term completeness
    doc 12
      freq 1
      pos 1936
  term completesnpinterval
    doc 0
      freq 1
      pos 7143
  term completing
    doc 2
      freq 2
      pos 2150
      pos 3679
  term complex
    doc 2
      freq 1
      pos 5594
    doc 10
      freq 1
      pos 1728
    doc 12
      freq 2
      pos 3828
      pos 4306
    doc 14
      freq 1
      pos 2879
    doc 15
      freq 3
      pos 971
      pos 1237
      pos 3120
  term complexity
    doc 13
      freq 1
      pos 1688
    doc 14
      freq 3
      pos 2449
      pos 2817
      pos 2828
  term complianc
    doc 0
      freq 10
      pos 1035
      pos 14382
      pos 14386
      pos 14391
      pos 14425
      pos 14551
      pos 14556
      pos 14591
      pos 14762
      pos 14787
    doc 10
      freq 4
      pos 229
      pos 5940
      pos 5969
      pos 6100
  term compliant
    doc 0
      freq 1
      pos 275
    doc 10
      freq 3
      pos 708
      pos 882
      pos 8564
    doc 17
      freq 1
      pos 1358
  term complicat
    doc 10
      freq 1
      pos 5897
  term complicated
    doc 10
      freq 2
      pos 1595
      pos 10426
  term component
    doc 6
      freq 3
      pos 1073
      pos 1679
      pos 2451
    doc 10
      freq 2
      pos 4949
      pos 5166
    doc 12
      freq 2
      pos 3518
      pos 6527
    doc 17
      freq 2
      pos 1702
      pos 1725
  term components
    doc 6
      freq 2
      pos 1144
      pos 1150
    doc 10
      freq 2
      pos 4866
      pos 5231
    doc 11
      freq 1
      pos 2099
  term compos
    doc 16
      freq 1
      pos 325
  term composed
    doc 2
      freq 1
      pos 1825
    doc 6
      freq 1
      pos 499
  term compound
    doc 13
      freq 1
      pos 3199
  term comprehensiv
    doc 2
      freq 1
      pos 4192
    doc 11
      freq 3
      pos 684
      pos 4212
      pos 9386
  term compressed
    doc 10
      freq 2
      pos 12193
      pos 12347
    doc 11
      freq 2
      pos 9745
      pos 9764
    doc 16
      freq 1
      pos 1740
  term compressing
    doc 7
      freq 3
      pos 1005
      pos 1959
      pos 2492
  term compression
    doc 7
      freq 1
      pos 2819
  term compris
    doc 2
      freq 2
      pos 420
      pos 448
    doc 6
      freq 1
      pos 1683
  term comprises
    doc 6
      freq 1
      pos 1658
  term compromis
    doc 17
      freq 3
      pos 1443
      pos 1459
      pos 1574
  term compromised
    doc 0
      freq 1
      pos 16578
  term compromising
    doc 10
      freq 1
      pos 11187
  term comput
    doc 6
      freq 2
      pos 802
      pos 1719
    doc 10
      freq 1
      pos 5509
  term computation
    doc 0
      freq 1
      pos 5188
    doc 5
      freq 1
      pos 110
    doc 14
      freq 1
      pos 481
  term computational
    doc 6
      freq 1
      pos 2524
    doc 14
      freq 2
      pos 2448
      pos 2827
  term computationally
    doc 14
      freq 2
      pos 1162
      pos 2878
    doc 18
      freq 1
      pos 1694
  term computed
    doc 5
      freq 1
      pos 1137
    doc 6
      freq 2
      pos 1212
      pos 1914
    doc 9
      freq 2
      pos 824
      pos 1444
  term computer
    doc 0
      freq 2
      pos 1109
      pos 17201
    doc 2
      freq 1
      pos 2863
    doc 11
      freq 2
      pos 10591
      pos 10594
    doc 13
      freq 1
      pos 7061
    doc 15
      freq 1
      pos 4025
  term computers
    doc 13
      freq 1
      pos 918
  term computes
    doc 10
      freq 1
      pos 1906
  term computing
    doc 0
      freq 1
      pos 12851
    doc 4
      freq 1
      pos 1332
  term concatenated
    doc 3
      freq 1
      pos 473
    doc 8
      freq 1
      pos 1024
  term concatenates
    doc 16
      freq 1
      pos 631
  term concatenating
    doc 0
      freq 1
      pos 10741
    doc 11
      freq 1
      pos 903
  term concatenation
    doc 0
      freq 1
      pos 6673
  term conceivably
    doc 10
      freq 3
      pos 9150
      pos 9855
      pos 9959
  term concept
    doc 10
      freq 1
      pos 1557
    doc 15
      freq 1
      pos 3161
  term concepts
    doc 12
      freq 1
      pos 7002
    doc 14
      freq 1
      pos 5367
  term concern
    doc 6
      freq 1
      pos 2865
    doc 12
      freq 1
      pos 3588
    doc 14
      freq 1
      pos 2684
    doc 18
      freq 1
      pos 1907
  term concerned
    doc 18
      freq 1
      pos 433
  term concerning
    doc 3
      freq 1
      pos 844
  term concerns
    doc 7
      freq 2
      pos 1748
      pos 1763
    doc 10
      freq 2
      pos 5648
      pos 10160
    doc 12
      freq 1
      pos 1498
  term concert
    doc 13
      freq 2
      pos 825
      pos 3070
  term concerts
    doc 13
      freq 1
      pos 388
  term concord
    doc 10
      freq 1
      pos 13414
  term concret
    doc 5
      freq 1
      pos 1887
    doc 12
      freq 1
      pos 5315
  term concurrent
    doc 4
      freq 1
      pos 855
  term condition
    doc 3
      freq 3
      pos 3114
      pos 5358
      pos 5418
    doc 4
      freq 1
      pos 2389
    doc 6
      freq 3
      pos 997
      pos 1814
      pos 2457
    doc 12
      freq 1
      pos 8223
    doc 14
      freq 2
      pos 652
      pos 1467
  term conditions
    doc 1
      freq 1
      pos 4691
    doc 2
      freq 1
      pos 4042
    doc 3
      freq 1
      pos 2169
    doc 4
      freq 3
      pos 4658
      pos 4674
      pos 4725
    doc 6
      freq 2
      pos 954
      pos 2659
    doc 9
      freq 1
      pos 394
    doc 10
      freq 1
      pos 4531
    doc 11
      freq 2
      pos 4196
      pos 9332
    doc 14
      freq 3
      pos 5288
      pos 5309
      pos 5321
    skipList 
      level 0
        skipDoc 11
        skipDocFP 619092
        impacts 
          impact 
            freq 1
            norm 95
          impact 
            freq 2
            norm 101
          impact 
            freq 3
            norm 108
        impactsEnd 
  term conducted
    doc 7
      freq 1
      pos 316
  term conf
    doc 0
      freq 2
      pos 397
      pos 1042
  term conferences
    doc 13
      freq 2
      pos 375
      pos 1984
  term conferencing
    doc 13
      freq 1
      pos 6791
  term confidenc
    doc 17
      freq 1
      pos 1437
  term confident
    doc 12
      freq 1
      pos 2497
    doc 15
      freq 1
      pos 1374
  term confidential
    doc 13
      freq 2
      pos 6077
      pos 6106
  term confidentiality
    doc 4
      freq 3
      pos 229
      pos 4025
      pos 4051
    doc 5
      freq 3
      pos 914
      pos 3627
      pos 3682
    doc 13
      freq 2
      pos 6047
      pos 6117
  term configur
    doc 9
      freq 2
      pos 645
      pos 1431
    doc 12
      freq 2
      pos 5324
      pos 6369
    doc 13
      freq 1
      pos 3602
    doc 15
      freq 5
      pos 1453
      pos 1592
      pos 2262
      pos 2446
      pos 3368
  term configurabl
    doc 1
      freq 1
      pos 6412
    doc 4
      freq 1
      pos 1986
  term configuration
    doc 0
      freq 5
      pos 1360
      pos 2633
      pos 2642
      pos 5688
      pos 14025
    doc 1
      freq 10
      pos 2365
      pos 2668
      pos 3169
      pos 4504
      pos 4857
      pos 6671
      pos 7855
      pos 8695
      pos 8749
      pos 8824
    doc 3
      freq 9
      pos 294
      pos 642
      pos 2478
      pos 2731
      pos 3421
      pos 3596
      pos 5016
      pos 5025
      pos 5107
    doc 9
      freq 5
      pos 214
      pos 248
      pos 450
      pos 1067
      pos 1414
    doc 12
      freq 10
      pos 3913
      pos 4123
      pos 4438
      pos 6383
      pos 7187
      pos 7284
      pos 7289
      pos 7304
      pos 7444
      pos 7736
    doc 13
      freq 1
      pos 4414
    doc 15
      freq 34
      pos 27
      pos 97
      pos 103
      pos 154
      pos 207
      pos 320
      pos 376
      pos 392
      pos 444
      pos 560
      pos 612
      pos 868
      pos 1044
      pos 1070
      pos 1321
      pos 1817
      pos 1822
      pos 1913
      pos 2007
      pos 2049
      pos 2338
      pos 2580
      pos 2692
      pos 3094
      pos 3326
      pos 3379
      pos 3445
      pos 3452
      pos 3644
      pos 3732
      pos 3903
      pos 3953
      pos 3968
      pos 3991
    doc 17
      freq 1
      pos 1913
    skipList 
      level 0
        skipDoc 17
        skipDocFP 620868
        impacts 
          impact 
            freq 5
            norm 95
          impact 
            freq 34
            norm 104
        impactsEnd 
  term configurations
    doc 12
      freq 1
      pos 9400
    doc 15
      freq 3
      pos 2453
      pos 3464
      pos 3483
  term configured
    doc 0
      freq 38
      pos 502
      pos 533
      pos 846
      pos 871
      pos 1346
      pos 2367
      pos 2449
      pos 2510
      pos 2578
      pos 2591
      pos 2643
      pos 2693
      pos 2756
      pos 2790
      pos 2838
      pos 2874
      pos 2929
      pos 3013
      pos 3051
      pos 3151
      pos 3187
      pos 3336
      pos 3502
      pos 3583
      pos 4111
      pos 4684
      pos 4689
      pos 5447
      pos 6316
      pos 6324
      pos 9959
      pos 10010
      pos 10873
      pos 10909
      pos 13393
      pos 14810
      pos 15758
      pos 16857
    doc 1
      freq 10
      pos 2974
      pos 4346
      pos 4829
      pos 6485
      pos 6566
      pos 6606
      pos 6708
      pos 6723
      pos 6735
      pos 8509
    doc 3
      freq 5
      pos 1176
      pos 2090
      pos 3160
      pos 3915
      pos 4183
    doc 4
      freq 1
      pos 2664
    doc 9
      freq 3
      pos 1087
      pos 1132
      pos 1523
    doc 12
      freq 14
      pos 2220
      pos 2558
      pos 3888
      pos 3905
      pos 4472
      pos 4492
      pos 4517
      pos 4549
      pos 4692
      pos 4725
      pos 4745
      pos 4768
      pos 5096
      pos 5992
    doc 15
      freq 5
      pos 413
      pos 1059
      pos 2198
      pos 2387
      pos 2712
  term configures
    doc 1
      freq 1
      pos 4850
  term configuring
    doc 12
      freq 5
      pos 2050
      pos 2161
      pos 2170
      pos 5302
      pos 5410
    doc 17
      freq 1
      pos 1772
  term confirm
    doc 12
      freq 1
      pos 8524
    doc 13
      freq 1
      pos 4846
  term conflict
    doc 15
      freq 1
      pos 2121
  term conflicting
    doc 3
      freq 1
      pos 5132
    doc 11
      freq 1
      pos 8238
    doc 17
      freq 1
      pos 965
  term conflicts
    doc 12
      freq 1
      pos 7869
  term conformanc
    doc 0
      freq 2
      pos 14361
      pos 17086
    doc 9
      freq 1
      pos 1093
  term conformant
    doc 0
      freq 2
      pos 6125
      pos 14368
  term conforms
    doc 3
      freq 1
      pos 417
    doc 10
      freq 1
      pos 7455
  term confusing
    doc 10
      freq 1
      pos 8704
  term confusion
    doc 0
      freq 7
      pos 13129
      pos 13231
      pos 13323
      pos 13448
      pos 13534
      pos 13638
      pos 13728
    doc 14
      freq 1
      pos 2127
  term congdon
    doc 2
      freq 2
      pos 3159
      pos 3470
  term congested
    doc 3
      freq 1
      pos 5288
  term congestion
    doc 3
      freq 1
      pos 5398
    doc 4
      freq 2
      pos 2263
      pos 2278
    doc 6
      freq 3
      pos 132
      pos 2309
      pos 2735
    doc 13
      freq 5
      pos 275
      pos 2540
      pos 4197
      pos 4204
      pos 5645
  term conjunction
    doc 0
      freq 2
      pos 10362
      pos 16900
    doc 12
      freq 3
      pos 836
      pos 6970
      pos 8378
    doc 17
      freq 1
      pos 1759
  term connect
    doc 1
      freq 1
      pos 8783
    doc 12
      freq 1
      pos 3624
  term connected
    doc 1
      freq 2
      pos 3299
      pos 8468
    doc 10
      freq 1
      pos 3706
    doc 12
      freq 3
      pos 1317
      pos 2571
      pos 2624
    doc 13
      freq 6
      pos 879
      pos 958
      pos 2483
      pos 2486
      pos 3808
      pos 3817
    doc 15
      freq 1
      pos 475
  term connecting
    doc 1
      freq 1
      pos 3075
  term connection
    doc 1
      freq 2
      pos 2735
      pos 8564
    doc 3
      freq 1
      pos 5309
    doc 10
      freq 7
      pos 287
      pos 2637
      pos 10011
      pos 10031
      pos 10064
      pos 10273
      pos 10291
    doc 11
      freq 3
      pos 4433
      pos 4578
      pos 8308
    doc 12
      freq 2
      pos 5581
      pos 7147
    doc 13
      freq 6
      pos 186
      pos 194
      pos 2433
      pos 2536
      pos 2578
      pos 3169
  term connectionless
    doc 0
      freq 1
      pos 16907
    doc 7
      freq 1
      pos 259
  term connections
    doc 1
      freq 2
      pos 5409
      pos 8453
    doc 10
      freq 1
      pos 10234
    doc 12
      freq 1
      pos 3732
    doc 13
      freq 3
      pos 2436
      pos 4155
      pos 5159
  term connectivity
    doc 3
      freq 2
      pos 1567
      pos 4673
    doc 8
      freq 1
      pos 1822
    doc 12
      freq 8
      pos 2677
      pos 2768
      pos 3204
      pos 3361
      pos 3613
      pos 3777
      pos 3873
      pos 3930
    doc 13
      freq 7
      pos 167
      pos 272
      pos 792
      pos 2007
      pos 4066
      pos 4082
      pos 4173
    doc 15
      freq 4
      pos 1148
      pos 1179
      pos 1195
      pos 2837
  term connects
    doc 1
      freq 2
      pos 3379
      pos 8441
    doc 3
      freq 2
      pos 1331
      pos 1340
  term consecutiv
    doc 0
      freq 11
      pos 12883
      pos 13137
      pos 13239
      pos 13456
      pos 13554
      pos 13646
      pos 13748
      pos 13821
      pos 13893
      pos 14033
      pos 14162
  term consensus
    doc 4
      freq 1
      pos 4852
    doc 7
      freq 1
      pos 1153
    doc 8
      freq 5
      pos 241
      pos 547
      pos 877
      pos 1203
      pos 1384
    doc 12
      freq 1
      pos 3952
    doc 15
      freq 2
      pos 3605
      pos 3686
  term consequenc
    doc 5
      freq 1
      pos 3473
    doc 10
      freq 1
      pos 7969
    doc 11
      freq 1
      pos 6569
    doc 12
      freq 1
      pos 1809
  term consequences
    doc 12
      freq 1
      pos 1650
  term consequently
    doc 10
      freq 3
      pos 3695
      pos 5911
      pos 10671
    doc 13
      freq 1
      pos 4485
    doc 14
      freq 8
      pos 1931
      pos 2027
      pos 3861
      pos 4607
      pos 5039
      pos 5175
      pos 5291
      pos 5327
  term conservativ
    doc 7
      freq 2
      pos 1243
      pos 1279
  term consider
    doc 0
      freq 2
      pos 5184
      pos 16721
    doc 1
      freq 1
      pos 7730
    doc 2
      freq 4
      pos 1920
      pos 5364
      pos 5835
      pos 5902
    doc 3
      freq 2
      pos 3789
      pos 3833
    doc 6
      freq 1
      pos 1696
    doc 7
      freq 1
      pos 562
    doc 8
      freq 1
      pos 400
    doc 10
      freq 2
      pos 6189
      pos 6817
    doc 11
      freq 1
      pos 9330
    doc 12
      freq 10
      pos 1019
      pos 1975
      pos 2656
      pos 2826
      pos 3236
      pos 3442
      pos 3651
      pos 4443
      pos 4945
      pos 6179
    doc 15
      freq 2
      pos 1436
      pos 1646
    skipList 
      level 0
        skipDoc 10
        skipDocFP 628448
        impacts 
          impact 
            freq 1
            norm 97
          impact 
            freq 2
            norm 107
          impact 
            freq 4
            norm 108
        impactsEnd 
  term considerabl
    doc 2
      freq 1
      pos 1115
    doc 6
      freq 1
      pos 302
  term considerably
    doc 7
      freq 1
      pos 605
    doc 10
      freq 1
      pos 9357
    doc 13
      freq 1
      pos 5626
  term consideration
    doc 7
      freq 1
      pos 1469
    doc 12
      freq 2
      pos 2787
      pos 4056
  term considerations
    doc 0
      freq 4
      pos 163
      pos 170
      pos 15808
      pos 15978
    doc 1
      freq 9
      pos 352
      pos 364
      pos 384
      pos 7364
      pos 7742
      pos 7929
      pos 7978
      pos 8408
      pos 8425
    doc 2
      freq 6
      pos 156
      pos 1942
      pos 2197
      pos 3122
      pos 6191
      pos 6199
    doc 3
      freq 12
      pos 264
      pos 268
      pos 303
      pos 544
      pos 548
      pos 1686
      pos 3784
      pos 4029
      pos 4067
      pos 4080
      pos 5282
      pos 5432
    doc 4
      freq 6
      pos 224
      pos 240
      pos 4021
      pos 4743
      pos 5826
      pos 5916
    doc 5
      freq 7
      pos 300
      pos 329
      pos 2742
      pos 2784
      pos 2824
      pos 3694
      pos 4152
    doc 6
      freq 1
      pos 2768
    doc 7
      freq 4
      pos 142
      pos 146
      pos 1680
      pos 1732
    doc 8
      freq 5
      pos 118
      pos 166
      pos 336
      pos 1678
      pos 1736
    doc 9
      freq 2
      pos 134
      pos 1010
    doc 10
      freq 13
      pos 213
      pos 219
      pos 265
      pos 269
      pos 307
      pos 3503
      pos 4310
      pos 4675
      pos 7768
      pos 8207
      pos 8283
      pos 10994
      pos 11444
    doc 11
      freq 3
      pos 533
      pos 9310
      pos 9323
    doc 12
      freq 59
      pos 22
      pos 69
      pos 93
      pos 109
      pos 136
      pos 186
      pos 239
      pos 352
      pos 370
      pos 411
      pos 434
      pos 452
      pos 501
      pos 513
      pos 538
      pos 559
      pos 672
      pos 687
      pos 701
      pos 865
      pos 1223
      pos 1231
      pos 1516
      pos 1560
      pos 1945
      pos 2138
      pos 2279
      pos 2650
      pos 3022
      pos 3386
      pos 3784
      pos 3815
      pos 4197
      pos 4204
      pos 4562
      pos 4919
      pos 5013
      pos 5422
      pos 5858
      pos 6006
      pos 6105
      pos 6133
      pos 6248
      pos 6494
      pos 6499
      pos 6641
      pos 6835
      pos 6851
      pos 6986
      pos 7233
      pos 7462
      pos 7706
      pos 7886
      pos 7897
      pos 8239
      pos 8636
      pos 9048
      pos 9420
      pos 9471
    doc 13
      freq 2
      pos 307
      pos 5652
    doc 14
      freq 6
      pos 177
      pos 187
      pos 266
      pos 1880
      pos 2225
      pos 5276
    doc 15
      freq 3
      pos 288
      pos 3810
      pos 3815
    doc 16
      freq 3
      pos 1599
      pos 1608
      pos 1640
    doc 17
      freq 2
      pos 1288
      pos 1944
    doc 18
      freq 2
      pos 174
      pos 1637
    skipList 
      level 0
        skipDoc 7
        skipDocFP 629756
        impacts 
          impact 
            freq 4
            norm 100
          impact 
            freq 7
            norm 104
          impact 
            freq 12
            norm 107
        impactsEnd 
        skipDoc 15
        skipDocFP 630661
        impacts 
          impact 
            freq 2
            norm 95
          impact 
            freq 5
            norm 97
          impact 
            freq 6
            norm 107
          impact 
            freq 59
            norm 113
        impactsEnd 
  term considered
    doc 0
      freq 2
      pos 15987
      pos 16119
    doc 1
      freq 4
      pos 3925
      pos 4904
      pos 8006
      pos 8686
    doc 2
      freq 3
      pos 5871
      pos 6127
      pos 6274
    doc 3
      freq 2
      pos 2318
      pos 3052
    doc 4
      freq 1
      pos 5000
    doc 7
      freq 5
      pos 327
      pos 602
      pos 1318
      pos 1337
      pos 1643
    doc 11
      freq 1
      pos 9390
    doc 12
      freq 8
      pos 1250
      pos 4238
      pos 4327
      pos 4400
      pos 5383
      pos 6885
      pos 7781
      pos 8209
    doc 13
      freq 1
      pos 6469
    doc 15
      freq 1
      pos 2496
    doc 16
      freq 2
      pos 921
      pos 955
    skipList 
      level 0
        skipDoc 12
        skipDocFP 633001
        impacts 
          impact 
            freq 5
            norm 100
          impact 
            freq 8
            norm 113
        impactsEnd 
  term considering
    doc 7
      freq 1
      pos 1285
    doc 12
      freq 4
      pos 3272
      pos 3491
      pos 4009
      pos 5733
    doc 13
      freq 2
      pos 551
      pos 1068
    doc 15
      freq 1
      pos 3090
  term considers
    doc 1
      freq 1
      pos 7371
  term consist
    doc 1
      freq 2
      pos 2195
      pos 3252
    doc 13
      freq 2
      pos 1304
      pos 4439
    doc 14
      freq 2
      pos 2804
      pos 2850
    doc 17
      freq 1
      pos 944
  term consistency
    doc 13
      freq 11
      pos 294
      pos 1665
      pos 3459
      pos 4186
      pos 4709
      pos 4753
      pos 4822
      pos 4848
      pos 4890
      pos 4982
      pos 6597
    doc 14
      freq 1
      pos 1323
    doc 15
      freq 3
      pos 1135
      pos 1866
      pos 1903
  term consistent
    doc 0
      freq 6
      pos 3814
      pos 3863
      pos 4314
      pos 4363
      pos 11178
      pos 11227
    doc 12
      freq 2
      pos 8851
      pos 9264
    doc 13
      freq 1
      pos 1750
    doc 15
      freq 3
      pos 2232
      pos 3463
      pos 3643
    doc 18
      freq 1
      pos 856
  term consisting
    doc 0
      freq 1
      pos 1510
    doc 1
      freq 1
      pos 469
    doc 13
      freq 1
      pos 1273
    doc 14
      freq 7
      pos 490
      pos 720
      pos 886
      pos 1128
      pos 1139
      pos 1261
      pos 1302
  term consists
    doc 1
      freq 4
      pos 3364
      pos 3511
      pos 3524
      pos 4779
    doc 3
      freq 1
      pos 452
    doc 6
      freq 1
      pos 1147
    doc 14
      freq 4
      pos 753
      pos 1444
      pos 1739
      pos 3238
  term constant
    doc 1
      freq 1
      pos 709
    doc 6
      freq 5
      pos 592
      pos 616
      pos 1200
      pos 1204
      pos 2299
  term constrain
    doc 10
      freq 1
      pos 10259
  term constrained
    doc 13
      freq 1
      pos 946
    doc 16
      freq 1
      pos 322
  term constraint
    doc 12
      freq 1
      pos 2628
  term constraints
    doc 10
      freq 1
      pos 3086
    doc 11
      freq 1
      pos 799
    doc 18
      freq 1
      pos 1566
  term construct
    doc 0
      freq 3
      pos 132
      pos 330
      pos 1145
    doc 1
      freq 1
      pos 3305
    doc 10
      freq 1
      pos 5114
    doc 16
      freq 2
      pos 1379
      pos 2296
    doc 18
      freq 1
      pos 98
  term constructed
    doc 10
      freq 1
      pos 12229
  term constructing
    doc 1
      freq 1
      pos 3352
    doc 11
      freq 1
      pos 9517
    doc 18
      freq 1
      pos 308
  term construction
    doc 10
      freq 1
      pos 7848
    doc 11
      freq 1
      pos 2174
  term constructiv
    doc 0
      freq 1
      pos 15907
  term consum
    doc 3
      freq 1
      pos 661
  term consumed
    doc 6
      freq 1
      pos 1258
  term consumer
    doc 6
      freq 2
      pos 926
      pos 2137
  term consumption
    doc 11
      freq 1
      pos 3936
    doc 13
      freq 2
      pos 3007
      pos 4491
  term cont
    doc 5
      freq 1
      pos 1617
    doc 11
      freq 1
      pos 3952
  term conta
    doc 1
      freq 1
      pos 8944
    doc 4
      freq 27
      pos 4
      pos 133
      pos 414
      pos 734
      pos 1003
      pos 1360
      pos 1747
      pos 2069
      pos 2306
      pos 2710
      pos 2956
      pos 3193
      pos 3429
      pos 3619
      pos 3791
      pos 4081
      pos 4491
      pos 4877
      pos 5148
      pos 5228
      pos 5393
      pos 5523
      pos 5808
      pos 6027
      pos 6045
      pos 6093
      pos 6427
    doc 8
      freq 1
      pos 2069
  term contact
    doc 0
      freq 1
      pos 1088
    doc 10
      freq 21
      pos 253
      pos 3451
      pos 4252
      pos 5169
      pos 5180
      pos 5380
      pos 5386
      pos 5889
      pos 6362
      pos 6647
      pos 6816
      pos 7162
      pos 7181
      pos 7991
      pos 8001
      pos 8225
      pos 8475
      pos 8709
      pos 8757
      pos 8795
      pos 8800
    doc 11
      freq 47
      pos 482
      pos 2068
      pos 2233
      pos 2352
      pos 2391
      pos 2396
      pos 2485
      pos 2591
      pos 2600
      pos 3152
      pos 3347
      pos 3810
      pos 4040
      pos 4159
      pos 4242
      pos 4298
      pos 4463
      pos 4693
      pos 4783
      pos 4873
      pos 4937
      pos 5173
      pos 5341
      pos 5489
      pos 5649
      pos 5947
      pos 6193
      pos 6271
      pos 6374
      pos 6878
      pos 6997
      pos 7571
      pos 7668
      pos 7851
      pos 8127
      pos 8177
      pos 8509
      pos 8652
      pos 8660
      pos 8670
      pos 8718
      pos 8755
      pos 8774
      pos 8845
      pos 8879
      pos 8906
      pos 9072
  term contacting
    doc 2
      freq 1
      pos 1280
  term contacts
    doc 2
      freq 1
      pos 3622
  term contain
    doc 0
      freq 5
      pos 1958
      pos 3739
      pos 4265
      pos 5280
      pos 13065
    doc 1
      freq 3
      pos 1402
      pos 2213
      pos 2991
    doc 3
      freq 3
      pos 1139
      pos 1191
      pos 2637
    doc 6
      freq 1
      pos 1052
    doc 7
      freq 2
      pos 1684
      pos 1707
    doc 10
      freq 9
      pos 2898
      pos 5158
      pos 5178
      pos 5575
      pos 5730
      pos 7756
      pos 7834
      pos 11974
      pos 12057
    doc 11
      freq 10
      pos 882
      pos 1001
      pos 1094
      pos 3939
      pos 4863
      pos 6511
      pos 7624
      pos 8977
      pos 8993
      pos 9000
    doc 12
      freq 1
      pos 1353
    doc 13
      freq 1
      pos 5717
    doc 14
      freq 3
      pos 496
      pos 2521
      pos 2534
    doc 16
      freq 2
      pos 113
      pos 1556
    skipList 
      level 0
        skipDoc 12
        skipDocFP 638824
        impacts 
          impact 
            freq 2
            norm 100
          impact 
            freq 3
            norm 107
          impact 
            freq 10
            norm 114
        impactsEnd 
  term contained
    doc 0
      freq 3
      pos 898
      pos 17242
      pos 17263
    doc 1
      freq 2
      pos 9623
      pos 9644
    doc 2
      freq 3
      pos 3534
      pos 6420
      pos 6441
    doc 3
      freq 3
      pos 2062
      pos 5972
      pos 5993
    doc 4
      freq 4
      pos 1500
      pos 4612
      pos 6127
      pos 6148
    doc 5
      freq 2
      pos 4457
      pos 4478
    doc 6
      freq 2
      pos 3252
      pos 3278
    doc 7
      freq 2
      pos 2962
      pos 2983
    doc 8
      freq 2
      pos 2179
      pos 2200
    doc 9
      freq 2
      pos 1824
      pos 1845
    doc 10
      freq 2
      pos 13485
      pos 13506
    doc 11
      freq 5
      pos 3464
      pos 4847
      pos 6268
      pos 10646
      pos 10667
    doc 12
      freq 2
      pos 9496
      pos 9517
    doc 13
      freq 4
      pos 5741
      pos 6133
      pos 7111
      pos 7132
    doc 14
      freq 2
      pos 5577
      pos 5598
    doc 15
      freq 2
      pos 4096
      pos 4117
    doc 16
      freq 3
      pos 2225
      pos 2707
      pos 2728
    doc 17
      freq 6
      pos 385
      pos 406
      pos 675
      pos 753
      pos 2431
      pos 2452
    doc 18
      freq 2
      pos 2219
      pos 2240
    skipList 
      level 0
        skipDoc 7
        skipDocFP 639985
        impacts 
          impact 
            freq 2
            norm 100
          impact 
            freq 3
            norm 107
          impact 
            freq 4
            norm 108
        impactsEnd 
        skipDoc 15
        skipDocFP 640485
        impacts 
          impact 
            freq 2
            norm 95
          impact 
            freq 4
            norm 109
          impact 
            freq 5
            norm 114
        impactsEnd 
  term containing
    doc 1
      freq 2
      pos 2508
      pos 7435
    doc 3
      freq 1
      pos 3101
    doc 10
      freq 11
      pos 3316
      pos 3814
      pos 5583
      pos 6031
      pos 6575
      pos 7293
      pos 7612
      pos 7698
      pos 8537
      pos 8737
      pos 10374
    doc 11
      freq 4
      pos 1009
      pos 1079
      pos 7703
      pos 8393
    doc 13
      freq 1
      pos 1298
    doc 14
      freq 11
      pos 209
      pos 931
      pos 1258
      pos 1299
      pos 2104
      pos 2135
      pos 2239
      pos 2246
      pos 2430
      pos 2508
      pos 2665
    doc 15
      freq 1
      pos 3562
    doc 17
      freq 1
      pos 1153
    skipList 
      level 0
        skipDoc 17
        skipDocFP 641781
        impacts 
          impact 
            freq 1
            norm 98
          impact 
            freq 11
            norm 107
        impactsEnd 
  term contains
    doc 0
      freq 28
      pos 465
      pos 590
      pos 625
      pos 643
      pos 733
      pos 763
      pos 781
      pos 800
      pos 839
      pos 863
      pos 896
      pos 2960
      pos 3146
      pos 3326
      pos 3418
      pos 3495
      pos 3601
      pos 4109
      pos 9379
      pos 9410
      pos 9458
      pos 9565
      pos 9609
      pos 9641
      pos 9802
      pos 9834
      pos 9866
      pos 13982
    doc 1
      freq 7
      pos 2091
      pos 3818
      pos 4389
      pos 4406
      pos 5046
      pos 5413
      pos 5428
    doc 4
      freq 1
      pos 4762
    doc 8
      freq 1
      pos 352
    doc 10
      freq 7
      pos 2380
      pos 3190
      pos 3343
      pos 7160
      pos 8079
      pos 8647
      pos 11665
    doc 11
      freq 45
      pos 575
      pos 773
      pos 856
      pos 1210
      pos 1611
      pos 1650
      pos 1659
      pos 1674
      pos 1696
      pos 1724
      pos 1748
      pos 1761
      pos 2306
      pos 2718
      pos 3212
      pos 3229
      pos 3475
      pos 3564
      pos 3701
      pos 3712
      pos 3922
      pos 3958
      pos 4086
      pos 4182
      pos 4232
      pos 4245
      pos 4747
      pos 4955
      pos 5719
      pos 5856
      pos 6042
      pos 6400
      pos 7007
      pos 7154
      pos 7172
      pos 7284
      pos 7370
      pos 7419
      pos 7563
      pos 7795
      pos 7899
      pos 8084
      pos 8658
      pos 8772
      pos 8877
    doc 14
      freq 10
      pos 2056
      pos 2585
      pos 2634
      pos 2723
      pos 2781
      pos 2799
      pos 3554
      pos 4522
      pos 4975
      pos 5148
    doc 16
      freq 2
      pos 332
      pos 1289
    doc 17
      freq 2
      pos 417
      pos 1014
    doc 18
      freq 1
      pos 693
    skipList 
      level 0
        skipDoc 16
        skipDocFP 642693
        impacts 
          impact 
            freq 1
            norm 97
          impact 
            freq 2
            norm 99
          impact 
            freq 10
            norm 107
          impact 
            freq 45
            norm 114
        impactsEnd 
  term contd
    doc 1
      freq 3
      pos 3687
      pos 3694
      pos 3701
  term contemplating
    doc 18
      freq 2
      pos 358
      pos 485
  term content
    doc 6
      freq 3
      pos 2750
      pos 2848
      pos 2857
    doc 7
      freq 1
      pos 939
    doc 10
      freq 10
      pos 2278
      pos 5206
      pos 6366
      pos 6370
      pos 6666
      pos 6670
      pos 7006
      pos 7090
      pos 7152
      pos 7381
    doc 11
      freq 73
      pos 255
      pos 263
      pos 438
      pos 457
      pos 1476
      pos 1497
      pos 1999
      pos 2247
      pos 3162
      pos 3360
      pos 3394
      pos 3398
      pos 3829
      pos 3833
      pos 3853
      pos 3857
      pos 3861
      pos 3867
      pos 3872
      pos 4033
      pos 4036
      pos 4156
      pos 4302
      pos 4305
      pos 4344
      pos 4356
      pos 4483
      pos 4487
      pos 4526
      pos 4535
      pos 4597
      pos 4605
      pos 4697
      pos 4701
      pos 4943
      pos 5059
      pos 5188
      pos 5192
      pos 5345
      pos 5349
      pos 5493
      pos 5497
      pos 5653
      pos 5657
      pos 5823
      pos 5973
      pos 5977
      pos 6197
      pos 6201
      pos 6888
      pos 6994
      pos 7222
      pos 7406
      pos 7537
      pos 7771
      pos 7790
      pos 7880
      pos 7884
      pos 8071
      pos 8171
      pos 8234
      pos 8239
      pos 8259
      pos 8343
      pos 8349
      pos 8352
      pos 8502
      pos 8505
      pos 8631
      pos 9101
      pos 9104
      pos 9216
      pos 9281
    doc 12
      freq 1
      pos 4632
    doc 13
      freq 38
      pos 197
      pos 235
      pos 564
      pos 628
      pos 807
      pos 863
      pos 872
      pos 1058
      pos 1287
      pos 1299
      pos 1570
      pos 1607
      pos 1698
      pos 1721
      pos 1873
      pos 1976
      pos 2000
      pos 2031
      pos 2616
      pos 2729
      pos 2748
      pos 2880
      pos 2920
      pos 2982
      pos 2995
      pos 3391
      pos 3409
      pos 3432
      pos 3488
      pos 3498
      pos 3515
      pos 3527
      pos 3550
      pos 4406
      pos 4720
      pos 4986
      pos 5215
      pos 5247
    doc 16
      freq 8
      pos 1157
      pos 1160
      pos 2017
      pos 2028
      pos 2038
      pos 2208
      pos 2216
      pos 2388
    doc 17
      freq 2
      pos 621
      pos 1273
    skipList 
      level 0
        skipDoc 17
        skipDocFP 644986
        impacts 
          impact 
            freq 2
            norm 98
          impact 
            freq 8
            norm 99
          impact 
            freq 38
            norm 109
          impact 
            freq 73
            norm 114
        impactsEnd 
  term contents
    doc 0
      freq 2
      pos 140
      pos 13359
    doc 1
      freq 2
      pos 213
      pos 8351
    doc 2
      freq 1
      pos 114
    doc 3
      freq 2
      pos 178
      pos 3337
    doc 4
      freq 1
      pos 150
    doc 5
      freq 1
      pos 256
    doc 7
      freq 1
      pos 114
    doc 8
      freq 1
      pos 107
    doc 9
      freq 1
      pos 116
    doc 10
      freq 2
      pos 180
      pos 4874
    doc 11
      freq 3
      pos 97
      pos 6071
      pos 7327
    doc 12
      freq 2
      pos 147
      pos 5057
    doc 13
      freq 2
      pos 134
      pos 5991
    doc 14
      freq 3
      pos 120
      pos 2471
      pos 2500
    doc 15
      freq 1
      pos 202
    doc 18
      freq 3
      pos 134
      pos 151
      pos 439
    skipList 
      level 0
        skipDoc 8
        skipDocFP 647563
        impacts 
          impact 
            freq 1
            norm 97
          impact 
            freq 2
            norm 107
        impactsEnd 
        skipDoc 18
        skipDocFP 647905
        impacts 
          impact 
            freq 1
            norm 95
          impact 
            freq 3
            norm 97
        impactsEnd 
  term context
    doc 1
      freq 3
      pos 2120
      pos 3182
      pos 5359
    doc 3
      freq 1
      pos 2938
    doc 5
      freq 7
      pos 520
      pos 536
      pos 672
      pos 1302
      pos 2264
      pos 2805
      pos 4080
    doc 10
      freq 4
      pos 120
      pos 1551
      pos 5958
      pos 7500
    doc 12
      freq 1
      pos 9245
    doc 13
      freq 2
      pos 1018
      pos 2614
    doc 15
      freq 1
      pos 2092
  term continu
    doc 0
      freq 1
      pos 4984
    doc 1
      freq 3
      pos 6122
      pos 6856
      pos 6945
    doc 7
      freq 1
      pos 1252
    doc 10
      freq 1
      pos 5698
    doc 12
      freq 1
      pos 3175
  term continually
    doc 13
      freq 1
      pos 3807
  term continuation
    doc 16
      freq 1
      pos 2500
  term continuations
    doc 16
      freq 1
      pos 1705
  term continued
    doc 2
      freq 2
      pos 3887
      pos 4311
    doc 11
      freq 1
      pos 1493
  term continuously
    doc 6
      freq 1
      pos 979
  term contrast
    doc 13
      freq 1
      pos 4322
  term contribut
    doc 13
      freq 1
      pos 1103
  term contributed
    doc 18
      freq 1
      pos 1999
  term contributes
    doc 5
      freq 1
      pos 1010
  term contributing
    doc 1
      freq 2
      pos 409
      pos 9183
    doc 11
      freq 1
      pos 9529
  term contribution
    doc 11
      freq 1
      pos 9505
  term contributions
    doc 1
      freq 1
      pos 8878
    doc 2
      freq 1
      pos 3478
    doc 4
      freq 2
      pos 4995
      pos 5293
    doc 6
      freq 1
      pos 3093
    doc 15
      freq 1
      pos 3891
  term contributor
    doc 0
      freq 1
      pos 17274
    doc 1
      freq 1
      pos 9655
    doc 2
      freq 1
      pos 6452
    doc 3
      freq 1
      pos 6004
    doc 4
      freq 1
      pos 6159
    doc 5
      freq 1
      pos 4489
    doc 6
      freq 1
      pos 3289
    doc 7
      freq 1
      pos 2994
    doc 8
      freq 1
      pos 2211
    doc 9
      freq 1
      pos 1856
    doc 10
      freq 1
      pos 13517
    doc 11
      freq 1
      pos 10678
    doc 12
      freq 1
      pos 9528
    doc 13
      freq 1
      pos 7143
    doc 14
      freq 1
      pos 5609
    doc 15
      freq 1
      pos 4128
    doc 16
      freq 1
      pos 2739
    doc 17
      freq 1
      pos 2463
    doc 18
      freq 1
      pos 2251
    skipList 
      level 0
        skipDoc 7
        skipDocFP 650441
        impacts 
          impact 
            freq 1
            norm 100
        impactsEnd 
        skipDoc 15
        skipDocFP 650746
        impacts 
          impact 
            freq 1
            norm 95
        impactsEnd 
  term contributors
    doc 3
      freq 2
      pos 285
      pos 4750
    doc 7
      freq 1
      pos 1796
  term control
    doc 0
      freq 9
      pos 507
      pos 3511
      pos 8062
      pos 8103
      pos 8157
      pos 8194
      pos 8258
      pos 16013
      pos 16774
    doc 1
      freq 45
      pos 318
      pos 327
      pos 338
      pos 392
      pos 2003
      pos 2532
      pos 2547
      pos 2553
      pos 2562
      pos 6286
      pos 6294
      pos 6377
      pos 6392
      pos 6400
      pos 6423
      pos 6464
      pos 6472
      pos 6491
      pos 6546
      pos 6573
      pos 6587
      pos 6613
      pos 6620
      pos 6678
      pos 6685
      pos 6714
      pos 6727
      pos 6742
      pos 6747
      pos 6772
      pos 6813
      pos 6862
      pos 6918
      pos 6951
      pos 7004
      pos 7022
      pos 7029
      pos 7047
      pos 7378
      pos 7986
      pos 8403
      pos 8681
      pos 9425
      pos 9430
      pos 9435
    doc 2
      freq 11
      pos 1258
      pos 1302
      pos 1349
      pos 2470
      pos 2493
      pos 2514
      pos 2545
      pos 2644
      pos 2678
      pos 2733
      pos 3315
    doc 3
      freq 28
      pos 251
      pos 259
      pos 302
      pos 397
      pos 663
      pos 2150
      pos 2158
      pos 2173
      pos 2293
      pos 2973
      pos 3145
      pos 3154
      pos 3198
      pos 3262
      pos 3265
      pos 3278
      pos 3398
      pos 3477
      pos 3517
      pos 3538
      pos 3565
      pos 3585
      pos 3625
      pos 4133
      pos 4204
      pos 4324
      pos 5281
      pos 5774
    doc 4
      freq 8
      pos 29
      pos 111
      pos 117
      pos 124
      pos 291
      pos 330
      pos 5217
      pos 5234
    doc 6
      freq 4
      pos 133
      pos 783
      pos 817
      pos 3052
    doc 7
      freq 19
      pos 756
      pos 884
      pos 1000
      pos 1063
      pos 1083
      pos 1092
      pos 2095
      pos 2109
      pos 2118
      pos 2126
      pos 2293
      pos 2329
      pos 2348
      pos 2488
      pos 2640
      pos 2676
      pos 2685
      pos 2820
      pos 2837
    doc 8
      freq 1
      pos 2115
    doc 10
      freq 2
      pos 4716
      pos 10107
    doc 12
      freq 1
      pos 6002
    doc 13
      freq 8
      pos 276
      pos 320
      pos 1429
      pos 4198
      pos 4205
      pos 4821
      pos 5646
      pos 6137
    skipList 
      level 0
        skipDoc 8
        skipDocFP 651604
        impacts 
          impact 
            freq 1
            norm 97
          impact 
            freq 19
            norm 100
          impact 
            freq 28
            norm 107
          impact 
            freq 45
            norm 113
        impactsEnd 
  term controlled
    doc 0
      freq 1
      pos 16166
    doc 2
      freq 1
      pos 1993
    doc 3
      freq 1
      pos 5732
    doc 6
      freq 1
      pos 2957
    doc 7
      freq 1
      pos 1842
  term controller
    doc 10
      freq 1
      pos 845
  term controls
    doc 0
      freq 2
      pos 7052
      pos 7063
    doc 17
      freq 1
      pos 1899
  term controversial
    doc 2
      freq 1
      pos 1155
  term convenienc
    doc 10
      freq 1
      pos 12343
  term convenient
    doc 1
      freq 2
      pos 3206
      pos 3237
    doc 13
      freq 2
      pos 2691
      pos 4360
  term convention
    doc 0
      freq 20
      pos 1012
      pos 1411
      pos 1434
      pos 1498
      pos 1583
      pos 1603
      pos 1635
      pos 1657
      pos 1702
      pos 1747
      pos 1798
      pos 1828
      pos 1854
      pos 1885
      pos 1911
      pos 1951
      pos 1972
      pos 1995
      pos 2022
      pos 2057
    doc 7
      freq 2
      pos 1015
      pos 2555
    doc 18
      freq 1
      pos 903
  term conventional
    doc 14
      freq 1
      pos 2575
  term conventions
    doc 0
      freq 4
      pos 152
      pos 950
      pos 17069
      pos 17119
    doc 10
      freq 3
      pos 5617
      pos 6479
      pos 7229
    doc 11
      freq 4
      pos 103
      pos 741
      pos 770
      pos 843
    doc 14
      freq 3
      pos 126
      pos 569
      pos 573
    doc 17
      freq 1
      pos 261
  term convergenc
    doc 0
      freq 3
      pos 16232
      pos 16491
      pos 16499
  term conversation
    doc 3
      freq 1
      pos 2935
  term conversely
    doc 13
      freq 1
      pos 5101
  term conversion
    doc 16
      freq 1
      pos 1116
  term convert
    doc 10
      freq 1
      pos 3037
  term converting
    doc 11
      freq 1
      pos 4619
  term convey
    doc 3
      freq 1
      pos 1586
    doc 6
      freq 1
      pos 774
    doc 12
      freq 1
      pos 4072
    doc 13
      freq 1
      pos 5659
  term conveyed
    doc 1
      freq 1
      pos 5961
  term conveying
    doc 10
      freq 2
      pos 145
      pos 157
  term cooper
    doc 1
      freq 1
      pos 9354
  term cooperated
    doc 2
      freq 2
      pos 68
      pos 217
  term cooperation
    doc 2
      freq 5
      pos 318
      pos 772
      pos 1728
      pos 3877
      pos 5398
  term coordinat
    doc 2
      freq 2
      pos 99
      pos 6024
  term coordinated
    doc 15
      freq 1
      pos 3482
  term coordination
    doc 2
      freq 1
      pos 3644
  term cope
    doc 4
      freq 1
      pos 1948
  term copied
    doc 2
      freq 1
      pos 616
    doc 4
      freq 5
      pos 2153
      pos 2819
      pos 3064
      pos 3300
      pos 3764
  term copies
    doc 0
      freq 1
      pos 17422
    doc 1
      freq 1
      pos 9803
    doc 2
      freq 1
      pos 6600
    doc 3
      freq 1
      pos 6152
    doc 4
      freq 1
      pos 6307
    doc 5
      freq 1
      pos 4637
    doc 6
      freq 1
      pos 3437
    doc 7
      freq 1
      pos 3142
    doc 8
      freq 1
      pos 2359
    doc 9
      freq 1
      pos 2004
    doc 10
      freq 1
      pos 13665
    doc 11
      freq 1
      pos 10826
    doc 12
      freq 1
      pos 9676
    doc 13
      freq 2
      pos 4775
      pos 7291
    doc 14
      freq 1
      pos 5757
    doc 15
      freq 1
      pos 4276
    doc 16
      freq 2
      pos 1098
      pos 2887
    doc 17
      freq 1
      pos 2611
    doc 18
      freq 1
      pos 2399
    skipList 
      level 0
        skipDoc 7
        skipDocFP 656981
        impacts 
          impact 
            freq 1
            norm 100
        impactsEnd 
        skipDoc 15
        skipDocFP 657286
        impacts 
          impact 
            freq 1
            norm 95
          impact 
            freq 2
            norm 109
        impactsEnd 
  term copy
    doc 0
      freq 1
      pos 7586
    doc 2
      freq 1
      pos 681
    doc 13
      freq 2
      pos 4801
      pos 4813
    doc 16
      freq 3
      pos 393
      pos 426
      pos 498
  term copying
    doc 10
      freq 1
      pos 9376
    doc 16
      freq 1
      pos 460
  term copyright
    doc 0
      freq 5
      pos 80
      pos 82
      pos 1209
      pos 17224
      pos 17226
    doc 1
      freq 4
      pos 97
      pos 99
      pos 9605
      pos 9607
    doc 2
      freq 4
      pos 50
      pos 52
      pos 6402
      pos 6404
    doc 3
      freq 4
      pos 91
      pos 93
      pos 5954
      pos 5956
    doc 4
      freq 4
      pos 93
      pos 95
      pos 6109
      pos 6111
    doc 5
      freq 4
      pos 77
      pos 79
      pos 4439
      pos 4441
    doc 6
      freq 4
      pos 53
      pos 55
      pos 3234
      pos 3236
    doc 7
      freq 4
      pos 64
      pos 66
      pos 2944
      pos 2946
    doc 8
      freq 4
      pos 58
      pos 60
      pos 2161
      pos 2163
    doc 9
      freq 4
      pos 79
      pos 81
      pos 1806
      pos 1808
    doc 10
      freq 4
      pos 82
      pos 84
      pos 13467
      pos 13469
    doc 11
      freq 4
      pos 66
      pos 68
      pos 10628
      pos 10630
    doc 12
      freq 4
      pos 56
      pos 58
      pos 9478
      pos 9480
    doc 13
      freq 4
      pos 65
      pos 67
      pos 7093
      pos 7095
    doc 14
      freq 4
      pos 60
      pos 62
      pos 5559
      pos 5561
    doc 15
      freq 4
      pos 64
      pos 66
      pos 4078
      pos 4080
    doc 16
      freq 4
      pos 78
      pos 80
      pos 2689
      pos 2691
    doc 17
      freq 4
      pos 75
      pos 77
      pos 2413
      pos 2415
    doc 18
      freq 4
      pos 84
      pos 86
      pos 2201
      pos 2203
    skipList 
      level 0
        skipDoc 7
        skipDocFP 658423
        impacts 
          impact 
            freq 4
            norm 100
          impact 
            freq 5
            norm 120
        impactsEnd 
        skipDoc 15
        skipDocFP 659072
        impacts 
          impact 
            freq 4
            norm 95
        impactsEnd 
  term copyright.html
    doc 6
      freq 1
      pos 3260
  term copyrighted
    doc 2
      freq 1
      pos 958
  term copyrights
    doc 0
      freq 1
      pos 17494
    doc 1
      freq 1
      pos 9875
    doc 2
      freq 1
      pos 6672
    doc 3
      freq 1
      pos 6224
    doc 4
      freq 1
      pos 6379
    doc 5
      freq 1
      pos 4709
    doc 6
      freq 1
      pos 3509
    doc 7
      freq 1
      pos 3214
    doc 8
      freq 1
      pos 2431
    doc 9
      freq 1
      pos 2076
    doc 10
      freq 1
      pos 13737
    doc 11
      freq 1
      pos 10898
    doc 12
      freq 1
      pos 9748
    doc 13
      freq 1
      pos 7363
    doc 14
      freq 1
      pos 5829
    doc 15
      freq 1
      pos 4348
    doc 16
      freq 1
      pos 2959
    doc 17
      freq 1
      pos 2683
    doc 18
      freq 1
      pos 2471
    skipList 
      level 0
        skipDoc 7
        skipDocFP 660450
        impacts 
          impact 
            freq 1
            norm 100
        impactsEnd 
        skipDoc 15
        skipDocFP 660755
        impacts 
          impact 
            freq 1
            norm 95
        impactsEnd 
  term core
    doc 1
      freq 1
      pos 1312
  term corporat
    doc 1
      freq 2
      pos 9255
      pos 9271
    doc 3
      freq 1
      pos 4785
  term corporation
    doc 2
      freq 1
      pos 3637
    doc 4
      freq 1
      pos 6047
    doc 9
      freq 1
      pos 622
  term correct
    doc 0
      freq 1
      pos 8198
    doc 4
      freq 1
      pos 4490
    doc 5
      freq 1
      pos 2472
    doc 6
      freq 1
      pos 1034
    doc 12
      freq 2
      pos 4227
      pos 5697
    doc 15
      freq 1
      pos 3461
  term corrected
    doc 2
      freq 1
      pos 4603
    doc 4
      freq 1
      pos 5562
    doc 6
      freq 1
      pos 2581
  term correction
    doc 13
      freq 1
      pos 2144
  term corrections
    doc 2
      freq 1
      pos 4559
  term correctly
    doc 4
      freq 1
      pos 4374
    doc 10
      freq 1
      pos 6026
    doc 15
      freq 1
      pos 2474
  term correctness
    doc 9
      freq 1
      pos 490
  term correlat
    doc 12
      freq 1
      pos 1000
  term correspond
    doc 1
      freq 2
      pos 1575
      pos 6704
    doc 10
      freq 7
      pos 2775
      pos 2814
      pos 2877
      pos 2927
      pos 4228
      pos 10654
      pos 11880
    doc 12
      freq 1
      pos 5093
    doc 14
      freq 4
      pos 828
      pos 1030
      pos 1521
      pos 1682
  term correspondenc
    doc 10
      freq 1
      pos 10744
  term correspondent
    doc 9
      freq 18
      pos 93
      pos 258
      pos 401
      pos 410
      pos 426
      pos 556
      pos 647
      pos 681
      pos 844
      pos 877
      pos 891
      pos 1012
      pos 1166
      pos 1335
      pos 1447
      pos 1468
      pos 1514
      pos 1610
  term corresponding
    doc 0
      freq 7
      pos 2170
      pos 2236
      pos 3846
      pos 4346
      pos 5321
      pos 6796
      pos 11210
    doc 1
      freq 4
      pos 2993
      pos 4731
      pos 5856
      pos 6969
    doc 3
      freq 2
      pos 957
      pos 1893
    doc 4
      freq 3
      pos 2480
      pos 3676
      pos 3842
    doc 5
      freq 1
      pos 3511
    doc 10
      freq 7
      pos 1641
      pos 2187
      pos 4299
      pos 4431
      pos 7878
      pos 7959
      pos 10629
    doc 12
      freq 4
      pos 1475
      pos 5160
      pos 5726
      pos 6229
    doc 14
      freq 7
      pos 637
      pos 1933
      pos 2064
      pos 2279
      pos 2923
      pos 3564
      pos 4532
    doc 18
      freq 2
      pos 967
      pos 1154
    skipList 
      level 0
        skipDoc 14
        skipDocFP 663235
        impacts 
          impact 
            freq 1
            norm 104
          impact 
            freq 7
            norm 107
        impactsEnd 
  term corresponds
    doc 0
      freq 4
      pos 5376
      pos 5611
      pos 8803
      pos 8859
    doc 3
      freq 2
      pos 1833
      pos 1920
    doc 10
      freq 4
      pos 3419
      pos 10066
      pos 10567
      pos 10584
  term corrigent
    doc 3
      freq 1
      pos 4917
  term corrigent.com
    doc 3
      freq 1
      pos 4928
  term corrupted
    doc 0
      freq 4
      pos 7311
      pos 7324
      pos 12944
      pos 12984
    doc 3
      freq 2
      pos 3032
      pos 3066
  term corruptedlspsdetected
    doc 0
      freq 1
      pos 7371
  term corruption
    doc 3
      freq 1
      pos 3045
    doc 4
      freq 1
      pos 672
  term cos
    doc 3
      freq 18
      pos 315
      pos 318
      pos 3959
      pos 3969
      pos 3976
      pos 3986
      pos 3992
      pos 5474
      pos 5543
      pos 5571
      pos 5601
      pos 5604
      pos 5616
      pos 5619
      pos 5629
      pos 5632
      pos 5667
      pos 5779
  term cosin
    doc 7
      freq 1
      pos 2021
  term cost
    doc 0
      freq 2
      pos 10957
      pos 11266
    doc 3
      freq 2
      pos 3299
      pos 4688
    doc 12
      freq 1
      pos 8171
  term costs
    doc 4
      freq 1
      pos 1830
    doc 18
      freq 1
      pos 449
  term could
    doc 1
      freq 6
      pos 2675
      pos 4514
      pos 8506
      pos 8527
      pos 8556
      pos 8614
    doc 2
      freq 2
      pos 1707
      pos 6272
    doc 3
      freq 2
      pos 3407
      pos 3417
    doc 4
      freq 3
      pos 968
      pos 2028
      pos 6021
    doc 6
      freq 2
      pos 2390
      pos 2636
    doc 7
      freq 4
      pos 325
      pos 1259
      pos 1396
      pos 1459
    doc 9
      freq 1
      pos 1470
    doc 10
      freq 18
      pos 3226
      pos 8669
      pos 8699
      pos 8857
      pos 8908
      pos 8960
      pos 8978
      pos 9149
      pos 9262
      pos 9331
      pos 9854
      pos 9964
      pos 10152
      pos 10217
      pos 11120
      pos 11238
      pos 11268
      pos 11299
    doc 11
      freq 14
      pos 1147
      pos 4112
      pos 4420
      pos 4819
      pos 4841
      pos 5113
      pos 5430
      pos 5876
      pos 6093
      pos 6111
      pos 6322
      pos 7060
      pos 7087
      pos 9009
    doc 12
      freq 30
      pos 972
      pos 1479
      pos 2184
      pos 2318
      pos 2963
      pos 3128
      pos 3365
      pos 3420
      pos 3524
      pos 3892
      pos 4336
      pos 4476
      pos 4487
      pos 4489
      pos 4512
      pos 4728
      pos 4900
      pos 4910
      pos 5323
      pos 5358
      pos 6079
      pos 6150
      pos 6422
      pos 6647
      pos 6882
      pos 8147
      pos 8457
      pos 8503
      pos 8920
      pos 9074
    doc 13
      freq 15
      pos 2921
      pos 3157
      pos 3197
      pos 3228
      pos 3249
      pos 3257
      pos 3274
      pos 3339
      pos 3584
      pos 4438
      pos 4546
      pos 4829
      pos 5061
      pos 5442
      pos 5583
    doc 14
      freq 7
      pos 453
      pos 2612
      pos 2643
      pos 2710
      pos 2745
      pos 2768
      pos 2856
    doc 15
      freq 7
      pos 973
      pos 995
      pos 1645
      pos 1857
      pos 2493
      pos 2504
      pos 3064
    doc 16
      freq 4
      pos 452
      pos 474
      pos 2474
      pos 2485
    doc 17
      freq 2
      pos 1729
      pos 1754
    doc 18
      freq 1
      pos 1082
    skipList 
      level 0
        skipDoc 10
        skipDocFP 665511
        impacts 
          impact 
            freq 1
            norm 95
          impact 
            freq 4
            norm 100
          impact 
            freq 6
            norm 113
          impact 
            freq 18
            norm 116
        impactsEnd 
        skipDoc 18
        skipDocFP 666271
        impacts 
          impact 
            freq 1
            norm 97
          impact 
            freq 2
            norm 98
          impact 
            freq 4
            norm 99
          impact 
            freq 7
            norm 104
          impact 
            freq 15
            norm 109
          impact 
            freq 30
            norm 113
        impactsEnd 
  term count
    doc 0
      freq 2
      pos 8244
      pos 15687
    doc 6
      freq 1
      pos 2046
    doc 11
      freq 21
      pos 1111
      pos 1135
      pos 1154
      pos 1184
      pos 2808
      pos 2819
      pos 2826
      pos 2833
      pos 2843
      pos 2851
      pos 2858
      pos 2864
      pos 2870
      pos 2879
      pos 2890
      pos 2897
      pos 2904
      pos 2912
      pos 3142
      pos 3155
      pos 4933
    doc 16
      freq 1
      pos 755
  term counted
    doc 0
      freq 8
      pos 7344
      pos 7366
      pos 7999
      pos 8469
      pos 8531
      pos 8588
      pos 12873
      pos 12954
    doc 6
      freq 1
      pos 2116
  term counter
    doc 0
      freq 2
      pos 684
      pos 13022
    doc 9
      freq 1
      pos 1302
    doc 11
      freq 1
      pos 4642
  term counter32
    doc 0
      freq 55
      pos 1027
      pos 7260
      pos 7262
      pos 7264
      pos 7266
      pos 7268
      pos 7270
      pos 7272
      pos 7274
      pos 7276
      pos 7278
      pos 7280
      pos 7282
      pos 7307
      pos 7379
      pos 7412
      pos 7445
      pos 7472
      pos 7502
      pos 7545
      pos 7572
      pos 7608
      pos 7655
      pos 7671
      pos 7706
      pos 7805
      pos 7809
      pos 7823
      pos 7825
      pos 7827
      pos 7829
      pos 7831
      pos 7833
      pos 7899
      pos 7967
      pos 8008
      pos 8038
      pos 8088
      pos 8142
      pos 8179
      pos 8213
      pos 8349
      pos 8351
      pos 8353
      pos 8355
      pos 8357
      pos 8359
      pos 8361
      pos 8427
      pos 8496
      pos 8554
      pos 8611
      pos 8668
      pos 8713
      pos 8758
  term countermeasures
    doc 5
      freq 5
      pos 3022
      pos 3221
      pos 3364
      pos 3484
      pos 3626
  term counters
    doc 0
      freq 7
      pos 667
      pos 669
      pos 693
      pos 1324
      pos 7215
      pos 7238
      pos 7762
    doc 2
      freq 1
      pos 3541
  term counts
    doc 0
      freq 5
      pos 714
      pos 7858
      pos 7884
      pos 7986
      pos 8380
  term coupl
    doc 12
      freq 1
      pos 1239
  term coupled
    doc 10
      freq 1
      pos 9120
  term cours
    doc 1
      freq 1
      pos 4678
    doc 10
      freq 3
      pos 1170
      pos 9750
      pos 10344
    doc 11
      freq 2
      pos 8714
      pos 8805
    doc 12
      freq 1
      pos 5268
  term court
    doc 1
      freq 1
      pos 9359
  term courtesy
    doc 12
      freq 15
      pos 299
      pos 2871
      pos 2897
      pos 3075
      pos 8143
      pos 8342
      pos 8370
      pos 8432
      pos 8538
      pos 8558
      pos 8705
      pos 8774
      pos 9019
      pos 9083
      pos 9349
  term cover
    doc 0
      freq 1
      pos 17505
    doc 1
      freq 1
      pos 9886
    doc 2
      freq 2
      pos 3812
      pos 6683
    doc 3
      freq 1
      pos 6235
    doc 4
      freq 1
      pos 6390
    doc 5
      freq 1
      pos 4720
    doc 6
      freq 1
      pos 3520
    doc 7
      freq 1
      pos 3225
    doc 8
      freq 1
      pos 2442
    doc 9
      freq 1
      pos 2087
    doc 10
      freq 1
      pos 13748
    doc 11
      freq 1
      pos 10909
    doc 12
      freq 1
      pos 9759
    doc 13
      freq 2
      pos 3188
      pos 7374
    doc 14
      freq 1
      pos 5840
    doc 15
      freq 1
      pos 4359
    doc 16
      freq 1
      pos 2970
    doc 17
      freq 1
      pos 2694
    doc 18
      freq 7
      pos 104
      pos 229
      pos 312
      pos 864
      pos 878
      pos 1060
      pos 2482
    skipList 
      level 0
        skipDoc 7
        skipDocFP 671181
        impacts 
          impact 
            freq 1
            norm 100
          impact 
            freq 2
            norm 108
        impactsEnd 
        skipDoc 15
        skipDocFP 671501
        impacts 
          impact 
            freq 1
            norm 95
          impact 
            freq 2
            norm 109
        impactsEnd 
  term coverag
    doc 13
      freq 3
      pos 211
      pos 3054
      pos 3061
  term covered
    doc 5
      freq 1
      pos 965
    doc 10
      freq 1
      pos 8687
    doc 11
      freq 1
      pos 6574
    doc 18
      freq 4
      pos 1076
      pos 1612
      pos 1943
      pos 1977
  term covering
    doc 14
      freq 1
      pos 5475
    doc 18
      freq 5
      pos 24
      pos 163
      pos 571
      pos 934
      pos 1789
  term covers
    doc 18
      freq 1
      pos 1273
  term cox
    doc 6
      freq 1
      pos 3116
  term cparam01
    doc 11
      freq 1
      pos 8724
  term cparam01.70710
    doc 11
      freq 1
      pos 8750
  term cparam02
    doc 11
      freq 1
      pos 8814
  term cparam02.70710
    doc 11
      freq 1
      pos 8840
  term cpjqvwy78d7th
    doc 10
      freq 1
      pos 12608
  term cpss
    doc 17
      freq 1
      pos 1825
  term cpu
    doc 6
      freq 1
      pos 2518
    doc 13
      freq 1
      pos 2226
  term cqdlshel5trvjh84jfhl7pdfv2zzypeevs3d3t8xokavzdo3yaad6sp4r8ncub
    doc 10
      freq 1
      pos 12501
  term cr
    doc 11
      freq 1
      pos 10542
  term crafted
    doc 10
      freq 1
      pos 12845
    doc 11
      freq 1
      pos 9347
  term cranberry
    doc 1
      freq 2
      pos 9578
      pos 9583
  term crazy
    doc 11
      freq 2
      pos 1918
      pos 1962
  term crc
    doc 3
      freq 1
      pos 3107
  term creat
    doc 0
      freq 48
      pos 3105
      pos 3237
      pos 3874
      pos 3886
      pos 3929
      pos 3959
      pos 4374
      pos 4386
      pos 5270
      pos 5319
      pos 5596
      pos 5629
      pos 5651
      pos 5735
      pos 5794
      pos 5831
      pos 5908
      pos 5959
      pos 6024
      pos 6084
      pos 6194
      pos 6218
      pos 10111
      pos 10160
      pos 10201
      pos 10246
      pos 10473
      pos 10510
      pos 10544
      pos 10620
      pos 10718
      pos 10818
      pos 11238
      pos 11283
      pos 11317
      pos 11356
      pos 11408
      pos 11459
      pos 11503
      pos 11536
      pos 11566
      pos 11600
      pos 14775
      pos 16114
      pos 16239
      pos 16613
      pos 16791
      pos 16879
    doc 1
      freq 2
      pos 2643
      pos 4140
    doc 2
      freq 2
      pos 1614
      pos 1630
    doc 4
      freq 1
      pos 657
    doc 7
      freq 1
      pos 355
    doc 10
      freq 6
      pos 4872
      pos 6571
      pos 7289
      pos 10926
      pos 11962
      pos 12045
    doc 12
      freq 3
      pos 4279
      pos 8830
      pos 9377
    doc 13
      freq 1
      pos 6390
    doc 16
      freq 3
      pos 105
      pos 191
      pos 373
    skipList 
      level 0
        skipDoc 13
        skipDocFP 673883
        impacts 
          impact 
            freq 1
            norm 100
          impact 
            freq 2
            norm 108
          impact 
            freq 3
            norm 113
          impact 
            freq 6
            norm 116
          impact 
            freq 48
            norm 120
        impactsEnd 
  term createandwait
    doc 0
      freq 5
      pos 3899
      pos 4411
      pos 5695
      pos 10130
      pos 11429
  term created
    doc 0
      freq 15
      pos 749
      pos 2263
      pos 2268
      pos 3156
      pos 3607
      pos 4123
      pos 5456
      pos 5570
      pos 8961
      pos 10020
      pos 10832
      pos 10842
      pos 10964
      pos 11372
      pos 11382
    doc 2
      freq 1
      pos 1667
    doc 5
      freq 4
      pos 3831
      pos 3863
      pos 3891
      pos 3921
    doc 7
      freq 1
      pos 515
    doc 8
      freq 1
      pos 339
    doc 10
      freq 2
      pos 11933
      pos 12013
    doc 11
      freq 1
      pos 1099
    doc 18
      freq 1
      pos 346
    skipList 
      level 0
        skipDoc 18
        skipDocFP 675660
        impacts 
          impact 
            freq 1
            norm 97
          impact 
            freq 4
            norm 104
          impact 
            freq 15
            norm 120
        impactsEnd 
  term creates
    doc 1
      freq 1
      pos 1483
    doc 10
      freq 2
      pos 6302
      pos 6941
    doc 18
      freq 1
      pos 1648
  term creating
    doc 0
      freq 2
      pos 5259
      pos 5530
    doc 1
      freq 1
      pos 1496
    doc 9
      freq 1
      pos 688
    doc 10
      freq 3
      pos 1379
      pos 9698
      pos 9773
    doc 12
      freq 1
      pos 8987
  term creation
    doc 0
      freq 1
      pos 5618
    doc 2
      freq 1
      pos 1549
    doc 10
      freq 1
      pos 11466
  term credentials
    doc 10
      freq 3
      pos 955
      pos 979
      pos 2619
  term crispin
    doc 16
      freq 3
      pos 2523
      pos 2546
      pos 2592
  term criter
    doc 0
      freq 2
      pos 552
      pos 4028
    doc 10
      freq 1
      pos 5976
  term critical
    doc 12
      freq 24
      pos 306
      pos 2879
      pos 3069
      pos 3269
      pos 8127
      pos 8210
      pos 8289
      pos 8298
      pos 8311
      pos 8391
      pos 8406
      pos 8452
      pos 8466
      pos 8536
      pos 8556
      pos 8585
      pos 8654
      pos 8703
      pos 8854
      pos 8905
      pos 8952
      pos 8979
      pos 9009
      pos 9107
    doc 13
      freq 1
      pos 4162
    doc 17
      freq 6
      pos 433
      pos 436
      pos 641
      pos 661
      pos 723
      pos 1569
  term criticality
    doc 17
      freq 1
      pos 632
  term crl
    doc 10
      freq 1
      pos 13247
    doc 17
      freq 1
      pos 2067
  term crlf
    doc 10
      freq 2
      pos 5245
      pos 5261
    doc 11
      freq 1
      pos 5729
  term crocker
    doc 9
      freq 1
      pos 1692
    doc 10
      freq 1
      pos 13185
    doc 16
      freq 1
      pos 2606
  term cross
    doc 10
      freq 1
      pos 1435
  term crossing
    doc 1
      freq 1
      pos 9356
  term crtl
    doc 8
      freq 9
      pos 1018
      pos 1036
      pos 1591
      pos 1596
      pos 1604
      pos 1612
      pos 1621
      pos 1630
      pos 1784
  term cruft
    doc 7
      freq 11
      pos 24
      pos 202
      pos 589
      pos 953
      pos 1303
      pos 1651
      pos 1825
      pos 2179
      pos 2537
      pos 2892
      pos 2939
  term crux
    doc 15
      freq 1
      pos 2157
  term cryptographic
    doc 0
      freq 2
      pos 16741
      pos 16819
    doc 5
      freq 3
      pos 519
      pos 535
      pos 1671
    doc 9
      freq 1
      pos 1711
    doc 10
      freq 6
      pos 508
      pos 642
      pos 1506
      pos 1539
      pos 12878
      pos 13203
    doc 17
      freq 3
      pos 1478
      pos 1651
      pos 1688
    doc 18
      freq 1
      pos 1741
  term cryptographically
    doc 10
      freq 1
      pos 104
    doc 12
      freq 2
      pos 5868
      pos 7547
  term cryptology
    doc 17
      freq 1
      pos 1682
  term cs
    doc 2
      freq 1
      pos 2870
  term cs.columbia.edu
    doc 11
      freq 1
      pos 10609
    doc 13
      freq 1
      pos 7075
  term csc
    doc 12
      freq 2
      pos 17
      pos 9456
  term cseq
    doc 10
      freq 11
      pos 4984
      pos 4999
      pos 5019
      pos 5045
      pos 6347
      pos 6632
      pos 7003
      pos 7149
      pos 7362
      pos 8229
      pos 8644
    doc 11
      freq 62
      pos 368
      pos 376
      pos 1345
      pos 1479
      pos 1985
      pos 2219
      pos 2380
      pos 2583
      pos 2696
      pos 2884
      pos 3350
      pos 3384
      pos 3530
      pos 3635
      pos 3826
      pos 4020
      pos 4143
      pos 4290
      pos 4470
      pos 4683
      pos 4759
      pos 4806
      pos 4921
      pos 4967
      pos 5045
      pos 5177
      pos 5333
      pos 5478
      pos 5638
      pos 5817
      pos 5960
      pos 6174
      pos 6363
      pos 6469
      pos 6632
      pos 6705
      pos 6728
      pos 6745
      pos 6783
      pos 6799
      pos 6814
      pos 6875
      pos 6981
      pos 7129
      pos 7212
      pos 7395
      pos 7526
      pos 7654
      pos 7759
      pos 7870
      pos 8056
      pos 8096
      pos 8141
      pos 8148
      pos 8340
      pos 8489
      pos 8617
      pos 8752
      pos 8842
      pos 8933
      pos 9091
      pos 9278
  term csma
    doc 2
      freq 1
      pos 2606
    doc 3
      freq 2
      pos 4437
      pos 4481
  term csnp
    doc 0
      freq 1
      pos 8674
  term csnps
    doc 0
      freq 2
      pos 7121
      pos 8695
  term ct
    doc 4
      freq 1
      pos 6052
  term ctdislwl7sxoorczai1ou9w
    doc 10
      freq 1
      pos 6284
  term ctrl
    doc 3
      freq 5
      pos 407
      pos 1986
      pos 3607
      pos 4086
      pos 4355
  term cucchiar
    doc 0
      freq 1
      pos 15918
  term cullen
    doc 10
      freq 1
      pos 13429
    doc 11
      freq 2
      pos 9473
      pos 9498
  term cumulativ
    doc 6
      freq 2
      pos 660
      pos 905
  term cupertin
    doc 3
      freq 1
      pos 4953
  term current
    doc 0
      freq 265
      pos 55
      pos 208
      pos 1175
      pos 1195
      pos 1413
      pos 1436
      pos 1500
      pos 1585
      pos 1620
      pos 1637
      pos 1659
      pos 1707
      pos 1752
      pos 1803
      pos 1830
      pos 1856
      pos 1887
      pos 1913
      pos 1953
      pos 1974
      pos 2000
      pos 2027
      pos 2062
      pos 2296
      pos 2339
      pos 2392
      pos 2474
      pos 2551
      pos 2620
      pos 2672
      pos 2730
      pos 2748
      pos 2777
      pos 2815
      pos 2863
      pos 2956
      pos 2982
      pos 3043
      pos 3142
      pos 3183
      pos 3239
      pos 3360
      pos 3414
      pos 3474
      pos 3529
      pos 3597
      pos 3702
      pos 3725
      pos 3779
      pos 3888
      pos 3931
      pos 3961
      pos 4023
      pos 4105
      pos 4214
      pos 4237
      pos 4291
      pos 4388
      pos 4464
      pos 4485
      pos 4532
      pos 4565
      pos 4591
      pos 4618
      pos 4658
      pos 4678
      pos 4742
      pos 4762
      pos 4831
      pos 4871
      pos 4970
      pos 5035
      pos 5147
      pos 5176
      pos 5206
      pos 5247
      pos 5416
      pos 5439
      pos 5519
      pos 5598
      pos 5631
      pos 5653
      pos 5737
      pos 5796
      pos 5833
      pos 5910
      pos 5961
      pos 6026
      pos 6086
      pos 6140
      pos 6196
      pos 6220
      pos 6282
      pos 6305
      pos 6388
      pos 6408
      pos 6449
      pos 6475
      pos 6509
      pos 6617
      pos 6727
      pos 6788
      pos 6847
      pos 6941
      pos 6988
      pos 7028
      pos 7106
      pos 7163
      pos 7211
      pos 7232
      pos 7293
      pos 7320
      pos 7393
      pos 7426
      pos 7451
      pos 7478
      pos 7520
      pos 7551
      pos 7578
      pos 7622
      pos 7661
      pos 7689
      pos 7722
      pos 7758
      pos 7779
      pos 7850
      pos 7905
      pos 7936
      pos 7973
      pos 8014
      pos 8053
      pos 8094
      pos 8148
      pos 8185
      pos 8219
      pos 8278
      pos 8307
      pos 8372
      pos 8400
      pos 8447
      pos 8515
      pos 8573
      pos 8631
      pos 8688
      pos 8733
      pos 8775
      pos 8834
      pos 8855
      pos 8920
      pos 8982
      pos 9013
      pos 9058
      pos 9103
      pos 9127
      pos 9153
      pos 9183
      pos 9257
      pos 9297
      pos 9327
      pos 9406
      pos 9454
      pos 9505
      pos 9537
      pos 9605
      pos 9637
      pos 9690
      pos 9719
      pos 9760
      pos 9830
      pos 9862
      pos 9922
      pos 9980
      pos 10004
      pos 10080
      pos 10113
      pos 10162
      pos 10203
      pos 10248
      pos 10475
      pos 10512
      pos 10546
      pos 10622
      pos 10720
      pos 10820
      pos 10894
      pos 10927
      pos 11078
      pos 11111
      pos 11156
      pos 11254
      pos 11285
      pos 11319
      pos 11358
      pos 11410
      pos 11461
      pos 11505
      pos 11538
      pos 11568
      pos 11602
      pos 11678
      pos 11718
      pos 11737
      pos 11806
      pos 11827
      pos 11851
      pos 11871
      pos 11905
      pos 11929
      pos 11951
      pos 11970
      pos 12043
      pos 12076
      pos 12133
      pos 12170
      pos 12202
      pos 12224
      pos 12243
      pos 12266
      pos 12320
      pos 12343
      pos 12367
      pos 12392
      pos 12420
      pos 12445
      pos 12483
      pos 12509
      pos 12539
      pos 12583
      pos 12610
      pos 12658
      pos 12661
      pos 12679
      pos 12734
      pos 12755
      pos 12793
      pos 12832
      pos 12925
      pos 13006
      pos 13079
      pos 13193
      pos 13282
      pos 13334
      pos 13413
      pos 13499
      pos 13598
      pos 13688
      pos 13791
      pos 13865
      pos 13950
      pos 14078
      pos 14206
      pos 14257
      pos 14388
      pos 14553
      pos 14764
      pos 15460
      pos 15528
      pos 15574
      pos 15609
      pos 15655
      pos 15679
      pos 15707
      pos 15749
      pos 15779
      pos 15896
    doc 1
      freq 2
      pos 72
      pos 2119
    doc 3
      freq 2
      pos 66
      pos 719
    doc 4
      freq 2
      pos 68
      pos 926
    doc 5
      freq 2
      pos 52
      pos 1657
    doc 7
      freq 1
      pos 1435
    doc 8
      freq 11
      pos 18
      pos 39
      pos 181
      pos 468
      pos 793
      pos 1120
      pos 1434
      pos 1664
      pos 1925
      pos 2148
      pos 2481
    doc 9
      freq 1
      pos 54
    doc 10
      freq 3
      pos 57
      pos 3201
      pos 9545
    doc 11
      freq 1
      pos 581
    doc 12
      freq 2
      pos 1355
      pos 1601
    doc 13
      freq 1
      pos 6561
    doc 15
      freq 2
      pos 1463
      pos 3689
    doc 16
      freq 5
      pos 53
      pos 871
      pos 876
      pos 944
      pos 1025
    doc 17
      freq 2
      pos 50
      pos 1155
    doc 18
      freq 1
      pos 59
    skipList 
      level 0
        skipDoc 9
        skipDocFP 681476
        impacts 
          impact 
            freq 1
            norm 95
          impact 
            freq 11
            norm 97
          impact 
            freq 265
            norm 120
        impactsEnd 
        skipDoc 18
        skipDocFP 686024
        impacts 
          impact 
            freq 1
            norm 97
          impact 
            freq 2
            norm 98
          impact 
            freq 5
            norm 99
        impactsEnd 
  term currently
    doc 0
      freq 2
      pos 11747
      pos 12086
    doc 1
      freq 1
      pos 8054
    doc 2
      freq 1
      pos 1341
    doc 5
      freq 3
      pos 1503
      pos 2091
      pos 2117
    doc 7
      freq 2
      pos 1325
      pos 1445
    doc 10
      freq 1
      pos 9519
    doc 15
      freq 1
      pos 690
    doc 16
      freq 3
      pos 933
      pos 968
      pos 1658
    skipList 
      level 0
        skipDoc 16
        skipDocFP 687011
        impacts 
          impact 
            freq 3
            norm 99
        impactsEnd 
  term curses
    doc 11
      freq 1
      pos 3852
  term cus
    doc 13
      freq 1
      pos 4376
  term custom
    doc 12
      freq 6
      pos 361
      pos 385
      pos 1528
      pos 4374
      pos 5261
      pos 5274
  term customer
    doc 0
      freq 1
      pos 16825
    doc 1
      freq 3
      pos 1042
      pos 1043
      pos 8189
    doc 3
      freq 6
      pos 507
      pos 617
      pos 618
      pos 2457
      pos 4054
      pos 5643
  term customer's
    doc 3
      freq 1
      pos 2408
  term customers
    doc 3
      freq 1
      pos 2391
  term customizabl
    doc 6
      freq 1
      pos 721
  term customization
    doc 13
      freq 4
      pos 4610
      pos 4628
      pos 4647
      pos 4693
  term customized
    doc 13
      freq 6
      pos 286
      pos 4373
      pos 4384
      pos 4540
      pos 4572
      pos 6020
  term customizing
    doc 13
      freq 1
      pos 4586
  term cut
    doc 7
      freq 1
      pos 1387
    doc 10
      freq 7
      pos 8276
      pos 8414
      pos 8430
      pos 8581
      pos 8671
      pos 8742
      pos 8868
    doc 12
      freq 1
      pos 8196
  term cutbacks
    doc 2
      freq 1
      pos 4817
  term cuw
    doc 11
      freq 1
      pos 10260
  term cw
    doc 3
      freq 4
      pos 3284
      pos 3316
      pos 3781
      pos 4310
    doc 11
      freq 1
      pos 9886
  term cxmlk8mlwq1
    doc 11
      freq 1
      pos 10484
  term cycle
    doc 9
      freq 1
      pos 1297
  term cyclic
    doc 3
      freq 1
      pos 3104
  term cyclically
    doc 13
      freq 1
      pos 2097
  term cycling
    doc 13
      freq 1
      pos 4126
  term cyv8o2u2vy6vrgyu3pxmnff6
    doc 11
      freq 1
      pos 9985
  term czajbgnvbaytalvtmqswcqydvqqidajnuzepma0ga1uebwwgqmlsb3hpmq0wcwyd
    doc 10
      freq 1
      pos 6904
  term d
    doc 0
      freq 14
      pos 1606
      pos 1705
      pos 1750
      pos 1801
      pos 1998
      pos 2025
      pos 2060
      pos 17016
      pos 17043
      pos 17064
      pos 17082
      pos 17135
      pos 17149
      pos 17178
    doc 1
      freq 4
      pos 8933
      pos 8939
      pos 8983
      pos 9198
    doc 2
      freq 11
      pos 2798
      pos 2829
      pos 2921
      pos 2923
      pos 3052
      pos 3069
      pos 3109
      pos 3189
      pos 3285
      pos 3387
      pos 3389
    doc 3
      freq 6
      pos 4316
      pos 4366
      pos 4535
      pos 4572
      pos 4592
      pos 4646
    doc 4
      freq 6
      pos 1414
      pos 1468
      pos 2752
      pos 2998
      pos 3234
      pos 3537
    doc 5
      freq 6
      pos 4186
      pos 4261
      pos 4263
      pos 4289
      pos 4357
      pos 4379
    doc 6
      freq 1
      pos 2970
    doc 8
      freq 5
      pos 1849
      pos 1873
      pos 2058
      pos 2064
      pos 2107
    doc 9
      freq 2
      pos 1651
      pos 1686
    doc 10
      freq 3
      pos 12795
      pos 13186
      pos 13234
    doc 11
      freq 4
      pos 10118
      pos 10295
      pos 10369
      pos 10388
    doc 12
      freq 1
      pos 7845
    doc 13
      freq 1
      pos 6812
    doc 14
      freq 1
      pos 5436
    doc 15
      freq 1
      pos 4056
    doc 16
      freq 1
      pos 2607
    doc 17
      freq 2
      pos 13
      pos 2054
    doc 18
      freq 3
      pos 2067
      pos 2088
      pos 2111
    skipList 
      level 0
        skipDoc 8
        skipDocFP 689414
        impacts 
          impact 
            freq 5
            norm 97
          impact 
            freq 6
            norm 104
          impact 
            freq 11
            norm 108
          impact 
            freq 14
            norm 120
        impactsEnd 
        skipDoc 16
        skipDocFP 690402
        impacts 
          impact 
            freq 2
            norm 95
          impact 
            freq 4
            norm 114
        impactsEnd 
  term d0b5d0b2d18fd182d18c202d20d0bfd180d0bed181d182d0
    doc 11
      freq 1
      pos 4005
  term d0bdd0be20d181d182
    doc 11
      freq 1
      pos 4003
  term d0be20d0b4d0b5d0b2d18fd0bdd0bed181d182d0be20d0b4
    doc 11
      freq 1
      pos 4004
  term d180d0b0d0b1d0bed182d0b0d18ed189d0b8d0b9
    doc 11
      freq 1
      pos 1974
  term d3o5eayuzwho2v5sbx8ubpaqij6kxz4rdq0drljsucsctvrsatikvexmsvgf
    doc 11
      freq 1
      pos 10233
  term d4simostn
    doc 10
      freq 1
      pos 12750
  term d8
    doc 2
      freq 1
      pos 1438
  term d87543
    doc 11
      freq 2
      pos 3785
      pos 3788
  term d8az1gubvt
    doc 11
      freq 1
      pos 10477
  term d8mw8z
    doc 11
      freq 1
      pos 10452
  term d8ocu9u4
    doc 10
      freq 1
      pos 12740
  term d8z
    doc 10
      freq 1
      pos 12508
  term d9
    doc 10
      freq 1
      pos 12763
  term d_t
    doc 5
      freq 1
      pos 2424
  term d_too
    doc 11
      freq 1
      pos 1925
  term daboo
    doc 16
      freq 1
      pos 2626
  term daigl
    doc 2
      freq 2
      pos 2228
      pos 6355
  term daksdj
    doc 11
      freq 1
      pos 7651
  term daley
    doc 15
      freq 1
      pos 3863
  term damas
    doc 18
      freq 1
      pos 2033
  term dan
    doc 1
      freq 1
      pos 9380
    doc 2
      freq 3
      pos 3461
      pos 3765
      pos 4035
    doc 3
      freq 1
      pos 4766
  term danger
    doc 9
      freq 1
      pos 1396
    doc 10
      freq 1
      pos 8133
    doc 18
      freq 4
      pos 1910
      pos 1958
      pos 1973
      pos 1994
  term daniel
    doc 0
      freq 1
      pos 17109
  term danny
    doc 11
      freq 1
      pos 9590
  term data
    doc 0
      freq 1
      pos 16437
    doc 1
      freq 8
      pos 131
      pos 387
      pos 452
      pos 609
      pos 714
      pos 7982
      pos 7989
      pos 7999
    doc 2
      freq 1
      pos 3920
    doc 3
      freq 6
      pos 111
      pos 352
      pos 463
      pos 3690
      pos 5376
      pos 5424
    doc 4
      freq 11
      pos 644
      pos 671
      pos 3588
      pos 3652
      pos 3659
      pos 3759
      pos 3817
      pos 3819
      pos 3942
      pos 4007
      pos 5621
    doc 5
      freq 18
      pos 178
      pos 290
      pos 407
      pos 437
      pos 458
      pos 2285
      pos 2328
      pos 2342
      pos 2421
      pos 2561
      pos 2607
      pos 2649
      pos 2719
      pos 2721
      pos 2727
      pos 2749
      pos 2941
      pos 3079
    doc 6
      freq 16
      pos 241
      pos 1185
      pos 1191
      pos 1221
      pos 1298
      pos 1306
      pos 1330
      pos 1350
      pos 1472
      pos 2252
      pos 2271
      pos 2294
      pos 2333
      pos 2433
      pos 2698
      pos 2709
    doc 7
      freq 3
      pos 1061
      pos 1919
      pos 2638
    doc 8
      freq 1
      pos 358
    doc 9
      freq 16
      pos 97
      pos 233
      pos 512
      pos 596
      pos 685
      pos 712
      pos 796
      pos 828
      pos 937
      pos 961
      pos 997
      pos 1258
      pos 1269
      pos 1373
      pos 1728
      pos 1799
    doc 10
      freq 1
      pos 13220
    doc 11
      freq 3
      pos 1097
      pos 4426
      pos 8069
    doc 12
      freq 54
      pos 301
      pos 308
      pos 461
      pos 472
      pos 479
      pos 746
      pos 944
      pos 2873
      pos 2881
      pos 2889
      pos 2899
      pos 3071
      pos 3077
      pos 5905
      pos 6663
      pos 6794
      pos 7637
      pos 8078
      pos 8107
      pos 8117
      pos 8125
      pos 8129
      pos 8145
      pos 8185
      pos 8200
      pos 8291
      pos 8344
      pos 8361
      pos 8372
      pos 8393
      pos 8434
      pos 8449
      pos 8468
      pos 8489
      pos 8502
      pos 8540
      pos 8546
      pos 8560
      pos 8646
      pos 8656
      pos 8701
      pos 8776
      pos 8856
      pos 8906
      pos 8954
      pos 8981
      pos 9021
      pos 9073
      pos 9085
      pos 9109
      pos 9242
      pos 9287
      pos 9351
      pos 9386
    doc 13
      freq 20
      pos 935
      pos 1336
      pos 1885
      pos 2146
      pos 2156
      pos 2233
      pos 2339
      pos 2450
      pos 3173
      pos 3400
      pos 3427
      pos 4185
      pos 4195
      pos 4347
      pos 5033
      pos 5354
      pos 5368
      pos 5581
      pos 6596
      pos 6605
    doc 15
      freq 5
      pos 696
      pos 703
      pos 911
      pos 1052
      pos 1137
    doc 16
      freq 22
      pos 118
      pos 153
      pos 333
      pos 480
      pos 494
      pos 506
      pos 621
      pos 1115
      pos 1126
      pos 1464
      pos 1475
      pos 1794
      pos 1822
      pos 1839
      pos 1947
      pos 2083
      pos 2175
      pos 2203
      pos 2315
      pos 2411
      pos 2430
      pos 2447
    skipList 
      level 0
        skipDoc 7
        skipDocFP 693183
        impacts 
          impact 
            freq 3
            norm 100
          impact 
            freq 16
            norm 101
          impact 
            freq 18
            norm 104
        impactsEnd 
        skipDoc 16
        skipDocFP 694315
        impacts 
          impact 
            freq 16
            norm 95
          impact 
            freq 22
            norm 99
          impact 
            freq 54
            norm 113
        impactsEnd 
  term databas
    doc 0
      freq 6
      pos 4877
      pos 4915
      pos 7458
      pos 11689
      pos 12063
      pos 15790
    doc 7
      freq 1
      pos 2594
    doc 15
      freq 2
      pos 1863
      pos 3651
  term databases
    doc 7
      freq 2
      pos 1683
      pos 1704
  term datacast
    doc 13
      freq 5
      pos 174
      pos 2013
      pos 2019
      pos 2112
      pos 3155
  term datagram
    doc 4
      freq 1
      pos 4666
    doc 11
      freq 7
      pos 211
      pos 3209
      pos 3226
      pos 3273
      pos 4557
      pos 8287
      pos 9228
    doc 12
      freq 1
      pos 3628
  term datalinkblocksiz
    doc 0
      freq 1
      pos 13882
  term date
    doc 10
      freq 28
      pos 2247
      pos 2267
      pos 3150
      pos 3165
      pos 3188
      pos 3230
      pos 3271
      pos 3291
      pos 4251
      pos 4288
      pos 5053
      pos 5160
      pos 5336
      pos 6353
      pos 6638
      pos 7069
      pos 7078
      pos 7137
      pos 7350
      pos 8226
      pos 8473
      pos 8503
      pos 8512
      pos 8555
      pos 8606
      pos 8629
      pos 8640
      pos 8758
    doc 11
      freq 8
      pos 332
      pos 3839
      pos 6033
      pos 6051
      pos 6074
      pos 6105
      pos 6116
      pos 6184
    doc 13
      freq 4
      pos 4006
      pos 4145
      pos 4800
      pos 5032
    doc 15
      freq 1
      pos 828
    doc 16
      freq 7
      pos 565
      pos 612
      pos 655
      pos 664
      pos 704
      pos 1980
      pos 2348
  term dattatr
    doc 0
      freq 1
      pos 15920
  term dave
    doc 1
      freq 1
      pos 9353
    doc 2
      freq 1
      pos 3463
    doc 15
      freq 1
      pos 3857
  term david
    doc 2
      freq 2
      pos 1332
      pos 6362
    doc 3
      freq 1
      pos 4915
    doc 11
      freq 1
      pos 9568
    doc 18
      freq 2
      pos 2021
      pos 2047
  term davidz
    doc 3
      freq 1
      pos 4927
  term davie
    doc 8
      freq 1
      pos 2083
  term davies
    doc 4
      freq 1
      pos 5504
    doc 12
      freq 1
      pos 7663
  term day
    doc 9
      freq 2
      pos 1342
      pos 1344
    doc 12
      freq 1
      pos 7403
  term days
    doc 8
      freq 1
      pos 455
    doc 12
      freq 1
      pos 6649
  term daz0dumol
    doc 10
      freq 1
      pos 6231
  term db8
    doc 12
      freq 4
      pos 2846
      pos 2863
      pos 5331
      pos 8425
  term dbjwnw
    doc 11
      freq 1
      pos 9999
  term dblreq
    doc 11
      freq 3
      pos 3328
      pos 3345
      pos 3381
  term dc2005
    doc 12
      freq 2
      pos 1321
      pos 7677
  term dckfulpccbdwhtzmslimmtbdr7aqqrpydcnqelynoqq
    doc 11
      freq 1
      pos 10446
  term dcooper
    doc 1
      freq 1
      pos 9364
  term ddds
    doc 10
      freq 1
      pos 13355
  term ddns
    doc 12
      freq 13
      pos 390
      pos 397
      pos 402
      pos 4413
      pos 4673
      pos 5429
      pos 5950
      pos 6099
      pos 6158
      pos 6188
      pos 6338
      pos 6396
      pos 6457
  term ddxe9cr8qtpdxmwjiyagrtx
    doc 10
      freq 1
      pos 12642
  term ddxeyocgfffsybkjyuf3iv77nzdwlrjxhqdxjazdtjt4pp4n3mtjuvd
    doc 11
      freq 1
      pos 10190
  term de
    doc 0
      freq 1
      pos 15969
    doc 2
      freq 1
      pos 2917
    doc 10
      freq 1
      pos 10927
  term deadlin
    doc 2
      freq 1
      pos 1838
  term deal
    doc 10
      freq 1
      pos 1734
  term deals
    doc 1
      freq 1
      pos 962
    doc 10
      freq 1
      pos 10767
  term deason
    doc 11
      freq 1
      pos 9527
  term debat
    doc 12
      freq 1
      pos 965
  term debugging
    doc 12
      freq 1
      pos 1155
  term decad
    doc 2
      freq 1
      pos 3892
  term decapsulated
    doc 1
      freq 2
      pos 1146
      pos 6168
    doc 3
      freq 1
      pos 801
  term decapsulating
    doc 3
      freq 1
      pos 1106
  term decapsulator
    doc 1
      freq 2
      pos 8295
      pos 8337
  term december
    doc 0
      freq 3
      pos 16978
      pos 17037
      pos 17193
    doc 2
      freq 2
      pos 2518
      pos 3196
    doc 4
      freq 6
      pos 5190
      pos 5210
      pos 5248
      pos 5391
      pos 5419
      pos 5436
    doc 7
      freq 1
      pos 617
    doc 9
      freq 1
      pos 1760
    doc 10
      freq 1
      pos 13323
    doc 12
      freq 2
      pos 7084
      pos 7296
    doc 15
      freq 1
      pos 3921
    doc 16
      freq 1
      pos 2603
    skipList 
      level 0
        skipDoc 15
        skipDocFP 700893
        impacts 
          impact 
            freq 1
            norm 95
          impact 
            freq 6
            norm 108
        impactsEnd 
  term decid
    doc 0
      freq 2
      pos 554
      pos 4030
    doc 1
      freq 1
      pos 4655
    doc 17
      freq 1
      pos 398
  term decided
    doc 2
      freq 2
      pos 4384
      pos 5938
  term decides
    doc 1
      freq 1
      pos 4698
    doc 12
      freq 2
      pos 5461
      pos 8696
  term deciding
    doc 1
      freq 1
      pos 4664
    doc 12
      freq 1
      pos 2065
  term decimal
    doc 8
      freq 4
      pos 952
      pos 958
      pos 1263
      pos 1458
    doc 14
      freq 1
      pos 2939
  term decision
    doc 6
      freq 1
      pos 116
    doc 7
      freq 1
      pos 452
    doc 10
      freq 4
      pos 4741
      pos 10317
      pos 10701
      pos 11387
    doc 12
      freq 1
      pos 4031
    doc 15
      freq 1
      pos 796
  term decisions
    doc 17
      freq 1
      pos 1876
  term decker
    doc 2
      freq 2
      pos 2897
      pos 3588
  term decod
    doc 11
      freq 1
      pos 870
  term decode_base64
    doc 10
      freq 1
      pos 12417
    doc 11
      freq 1
      pos 9822
  term decoder
    doc 6
      freq 1
      pos 2635
  term decoder's
    doc 6
      freq 1
      pos 2628
  term decoding
    doc 6
      freq 1
      pos 1262
    doc 10
      freq 1
      pos 12443
    doc 11
      freq 1
      pos 9850
  term decommissioning
    doc 7
      freq 2
      pos 122
      pos 302
  term decreas
    doc 18
      freq 1
      pos 1971
  term decreasing
    doc 2
      freq 1
      pos 1314
  term decrement
    doc 14
      freq 3
      pos 807
      pos 1507
      pos 1960
    doc 18
      freq 3
      pos 1293
      pos 1296
      pos 1320
  term decremented
    doc 14
      freq 1
      pos 3560
  term decrementing
    doc 14
      freq 2
      pos 1943
      pos 2220
  term decrements
    doc 4
      freq 1
      pos 3130
  term decrypt
    doc 4
      freq 2
      pos 1611
      pos 1627
  term dedicated
    doc 5
      freq 4
      pos 381
      pos 445
      pos 518
      pos 1399
    doc 6
      freq 2
      pos 2546
      pos 2591
    doc 13
      freq 1
      pos 3263
  term deduc
    doc 13
      freq 1
      pos 5530
  term deem
    doc 10
      freq 1
      pos 8496
  term deemed
    doc 2
      freq 1
      pos 1600
  term deep
    doc 2
      freq 1
      pos 5314
  term deeper
    doc 2
      freq 1
      pos 2121
  term deering
    doc 4
      freq 6
      pos 13
      pos 5177
      pos 5232
      pos 5334
      pos 5349
      pos 6059
    doc 12
      freq 1
      pos 7428
  term default
    doc 0
      freq 2
      pos 1713
      pos 1728
    doc 1
      freq 3
      pos 6282
      pos 6437
      pos 6449
    doc 3
      freq 4
      pos 2600
      pos 3906
      pos 3916
      pos 5699
    doc 4
      freq 1
      pos 2333
    doc 5
      freq 7
      pos 1198
      pos 1261
      pos 1303
      pos 1329
      pos 1356
      pos 1374
      pos 1888
    doc 7
      freq 3
      pos 347
      pos 761
      pos 2151
    doc 9
      freq 2
      pos 173
      pos 1246
    doc 10
      freq 4
      pos 11630
      pos 11725
      pos 11826
      pos 11920
    doc 11
      freq 1
      pos 4849
    doc 12
      freq 1
      pos 7804
    skipList 
      level 0
        skipDoc 10
        skipDocFP 704134
        impacts 
          impact 
            freq 2
            norm 95
          impact 
            freq 3
            norm 100
          impact 
            freq 7
            norm 104
        impactsEnd 
  term defaultmetric
    doc 0
      freq 1
      pos 10496
  term defaultmetrictyp
    doc 0
      freq 1
      pos 10530
  term defaults
    doc 4
      freq 2
      pos 1997
      pos 2027
  term defeat
    doc 12
      freq 1
      pos 1363
  term defensiv
    doc 16
      freq 1
      pos 1370
  term defer
    doc 13
      freq 1
      pos 4907
  term defin
    doc 0
      freq 2
      pos 14364
      pos 14371
    doc 1
      freq 2
      pos 753
      pos 2143
    doc 10
      freq 1
      pos 5752
    doc 11
      freq 2
      pos 849
      pos 4988
    doc 13
      freq 2
      pos 1857
      pos 4955
    doc 17
      freq 1
      pos 228
    doc 18
      freq 2
      pos 1228
      pos 1244
  term defined
    doc 0
      freq 6
      pos 255
      pos 259
      pos 5762
      pos 10287
      pos 15981
      pos 16098
    doc 1
      freq 12
      pos 1121
      pos 2292
      pos 2320
      pos 2327
      pos 2344
      pos 2438
      pos 2447
      pos 3743
      pos 6013
      pos 6100
      pos 7766
      pos 7816
    doc 2
      freq 4
      pos 1638
      pos 4207
      pos 4994
      pos 5068
    doc 3
      freq 15
      pos 777
      pos 923
      pos 1084
      pos 1708
      pos 1856
      pos 1983
      pos 2000
      pos 2153
      pos 3228
      pos 3252
      pos 3267
      pos 3281
      pos 3604
      pos 3628
      pos 5621
    doc 4
      freq 9
      pos 296
      pos 393
      pos 877
      pos 4758
      pos 4782
      pos 4911
      pos 5013
      pos 5035
      pos 5041
    doc 5
      freq 9
      pos 627
      pos 806
      pos 1699
      pos 1793
      pos 1881
      pos 2092
      pos 2118
      pos 2573
      pos 3742
    doc 6
      freq 4
      pos 86
      pos 273
      pos 1730
      pos 1832
    doc 7
      freq 1
      pos 1203
    doc 8
      freq 20
      pos 84
      pos 208
      pos 224
      pos 529
      pos 549
      pos 578
      pos 859
      pos 879
      pos 909
      pos 1101
      pos 1164
      pos 1185
      pos 1205
      pos 1234
      pos 1345
      pos 1366
      pos 1386
      pos 1415
      pos 1535
      pos 1555
    doc 9
      freq 2
      pos 379
      pos 1578
    doc 10
      freq 16
      pos 434
      pos 2883
      pos 3398
      pos 5118
      pos 5465
      pos 5738
      pos 9510
      pos 10757
      pos 11503
      pos 11603
      pos 11698
      pos 11799
      pos 11893
      pos 11988
      pos 11998
      pos 12082
    doc 11
      freq 6
      pos 590
      pos 827
      pos 1299
      pos 1371
      pos 1388
      pos 1857
    doc 12
      freq 1
      pos 1327
    doc 13
      freq 3
      pos 652
      pos 5492
      pos 6679
    doc 14
      freq 1
      pos 670
    doc 16
      freq 2
      pos 1427
      pos 1560
    doc 17
      freq 13
      pos 257
      pos 460
      pos 573
      pos 827
      pos 931
      pos 980
      pos 1094
      pos 1282
      pos 1291
      pos 1963
      pos 2255
      pos 2335
      pos 2361
    doc 18
      freq 1
      pos 1963
    skipList 
      level 0
        skipDoc 7
        skipDocFP 705795
        impacts 
          impact 
            freq 1
            norm 100
          impact 
            freq 4
            norm 101
          impact 
            freq 9
            norm 104
          impact 
            freq 15
            norm 107
        impactsEnd 
        skipDoc 16
        skipDocFP 706872
        impacts 
          impact 
            freq 2
            norm 95
          impact 
            freq 20
            norm 97
        impactsEnd 
  term defines
    doc 0
      freq 7
      pos 91
      pos 428
      pos 455
      pos 938
      pos 3985
      pos 10008
      pos 10931
    doc 2
      freq 1
      pos 1562
    doc 4
      freq 1
      pos 751
    doc 5
      freq 8
      pos 599
      pos 1505
      pos 1548
      pos 1689
      pos 1705
      pos 1723
      pos 1754
      pos 2671
    doc 6
      freq 1
      pos 178
    doc 10
      freq 5
      pos 123
      pos 2100
      pos 4505
      pos 5451
      pos 8041
    doc 11
      freq 2
      pos 808
      pos 6125
    doc 13
      freq 1
      pos 1030
    doc 14
      freq 2
      pos 29
      pos 382
    doc 16
      freq 1
      pos 1668
    doc 17
      freq 1
      pos 330
    doc 18
      freq 1
      pos 1211
    skipList 
      level 0
        skipDoc 13
        skipDocFP 708627
        impacts 
          impact 
            freq 1
            norm 101
          impact 
            freq 8
            norm 104
        impactsEnd 
  term defining
    doc 2
      freq 1
      pos 3554
    doc 3
      freq 1
      pos 3124
    doc 4
      freq 1
      pos 5045
    doc 5
      freq 2
      pos 2584
      pos 3753
    doc 6
      freq 1
      pos 718
    doc 10
      freq 1
      pos 137
    doc 12
      freq 1
      pos 5707
    doc 18
      freq 1
      pos 1338
    skipList 
      level 0
        skipDoc 18
        skipDocFP 709604
        impacts 
          impact 
            freq 1
            norm 97
          impact 
            freq 2
            norm 104
        impactsEnd 
  term definition
    doc 0
      freq 6
      pos 155
      pos 351
      pos 1001
      pos 2106
      pos 2223
      pos 2249
    doc 2
      freq 2
      pos 3538
      pos 6170
    doc 3
      freq 2
      pos 2925
      pos 5617
    doc 5
      freq 2
      pos 1561
      pos 1569
    doc 6
      freq 1
      pos 722
    doc 8
      freq 2
      pos 1633
      pos 1651
    doc 10
      freq 3
      pos 933
      pos 3439
      pos 5146
    doc 11
      freq 1
      pos 1404
    doc 13
      freq 1
      pos 1236
    doc 14
      freq 1
      pos 395
    doc 16
      freq 2
      pos 1540
      pos 1550
    doc 17
      freq 1
      pos 1269
    doc 18
      freq 1
      pos 1222
    skipList 
      level 0
        skipDoc 11
        skipDocFP 710166
        impacts 
          impact 
            freq 2
            norm 97
          impact 
            freq 3
            norm 116
          impact 
            freq 6
            norm 120
        impactsEnd 
  term definitions
    doc 0
      freq 11
      pos 356
      pos 364
      pos 388
      pos 1008
      pos 1273
      pos 1408
      pos 1894
      pos 1934
      pos 2103
      pos 12763
      pos 14362
    doc 2
      freq 10
      pos 2466
      pos 2906
      pos 2927
      pos 2997
      pos 3213
      pos 3230
      pos 3249
      pos 3375
      pos 3391
      pos 3754
    doc 7
      freq 13
      pos 876
      pos 985
      pos 1022
      pos 1055
      pos 1697
      pos 2007
      pos 2286
      pos 2304
      pos 2321
      pos 2340
      pos 2473
      pos 2567
      pos 2632
    doc 13
      freq 1
      pos 6704
    doc 17
      freq 3
      pos 469
      pos 2161
      pos 2193
  term definitiv
    doc 10
      freq 2
      pos 8104
      pos 9394
  term definitively
    doc 10
      freq 1
      pos 9308
  term defval
    doc 0
      freq 48
      pos 2313
      pos 2378
      pos 2521
      pos 2602
      pos 2654
      pos 2704
      pos 2763
      pos 2797
      pos 2845
      pos 2936
      pos 3020
      pos 3947
      pos 3978
      pos 4801
      pos 4857
      pos 5013
      pos 5162
      pos 5192
      pos 5216
      pos 5639
      pos 5819
      pos 5896
      pos 5929
      pos 6012
      pos 6126
      pos 6206
      pos 6423
      pos 6461
      pos 6493
      pos 6829
      pos 6923
      pos 6970
      pos 7010
      pos 7076
      pos 7145
      pos 7188
      pos 10189
      pos 10498
      pos 10532
      pos 10608
      pos 10705
      pos 10789
      pos 10854
      pos 11491
      pos 11524
      pos 11554
      pos 11588
      pos 11632
  term degrad
    doc 12
      freq 2
      pos 2448
      pos 2505
  term degre
    doc 1
      freq 1
      pos 8643
    doc 12
      freq 1
      pos 2423
    doc 17
      freq 1
      pos 1585
  term delay
    doc 0
      freq 3
      pos 2678
      pos 16231
      pos 16490
    doc 2
      freq 1
      pos 5610
    doc 5
      freq 4
      pos 1408
      pos 1959
      pos 2034
      pos 3322
    doc 6
      freq 10
      pos 1152
      pos 1162
      pos 1165
      pos 1466
      pos 1573
      pos 1599
      pos 2158
      pos 2177
      pos 2691
      pos 3016
    doc 12
      freq 1
      pos 3507
  term delayed
    doc 6
      freq 1
      pos 1478
  term delaying
    doc 0
      freq 1
      pos 16563
    doc 2
      freq 1
      pos 5589
  term delays
    doc 2
      freq 1
      pos 639
  term delegat
    doc 10
      freq 1
      pos 10468
    doc 12
      freq 1
      pos 6328
  term delegated
    doc 12
      freq 5
      pos 6217
      pos 6232
      pos 6236
      pos 6296
      pos 6378
    doc 17
      freq 1
      pos 1972
  term delegation
    doc 10
      freq 1
      pos 13352
    doc 12
      freq 8
      pos 406
      pos 1451
      pos 1472
      pos 3583
      pos 6162
      pos 6305
      pos 7161
      pos 7719
    doc 15
      freq 1
      pos 2516
    doc 18
      freq 1
      pos 1121
  term delegator
    doc 12
      freq 3
      pos 6208
      pos 6315
      pos 6335
  term delet
    doc 0
      freq 2
      pos 16792
      pos 16880
  term deleted
    doc 1
      freq 1
      pos 4859
    doc 13
      freq 2
      pos 4042
      pos 6507
    doc 16
      freq 3
      pos 1907
      pos 2102
      pos 2233
  term deleting
    doc 16
      freq 1
      pos 468
  term deletion
    doc 13
      freq 1
      pos 5802
  term delimiting
    doc 3
      freq 14
      pos 1822
      pos 2354
      pos 2442
      pos 2473
      pos 2492
      pos 2503
      pos 2556
      pos 2576
      pos 2614
      pos 2651
      pos 2680
      pos 2752
      pos 2793
      pos 2796
  term deliver
    doc 3
      freq 1
      pos 940
    doc 4
      freq 6
      pos 2286
      pos 2346
      pos 2368
      pos 2449
      pos 2604
      pos 2637
    doc 6
      freq 2
      pos 203
      pos 1635
    doc 7
      freq 1
      pos 1658
    doc 13
      freq 3
      pos 1042
      pos 1718
      pos 5423
  term delivered
    doc 1
      freq 1
      pos 1238
    doc 3
      freq 2
      pos 2945
      pos 3034
    doc 4
      freq 2
      pos 2254
      pos 2430
    doc 13
      freq 5
      pos 674
      pos 4435
      pos 4476
      pos 6026
      pos 6098
    doc 17
      freq 1
      pos 369
  term delivering
    doc 13
      freq 3
      pos 4003
      pos 5029
      pos 6582
  term delivery
    doc 3
      freq 2
      pos 3050
      pos 3733
    doc 6
      freq 19
      pos 22
      pos 181
      pos 292
      pos 328
      pos 492
      pos 539
      pos 686
      pos 745
      pos 911
      pos 1135
      pos 1142
      pos 1616
      pos 2031
      pos 2154
      pos 2345
      pos 2761
      pos 2914
      pos 3038
      pos 3228
    doc 13
      freq 54
      pos 115
      pos 207
      pos 262
      pos 283
      pos 629
      pos 1101
      pos 1126
      pos 1154
      pos 1229
      pos 1321
      pos 1422
      pos 1508
      pos 1575
      pos 1657
      pos 1973
      pos 2022
      pos 2032
      pos 2091
      pos 2195
      pos 2316
      pos 2338
      pos 2750
      pos 2850
      pos 2873
      pos 3319
      pos 3325
      pos 3374
      pos 3418
      pos 3436
      pos 3447
      pos 3674
      pos 3825
      pos 3867
      pos 3893
      pos 3927
      pos 3996
      pos 4061
      pos 4193
      pos 4272
      pos 4289
      pos 4309
      pos 4325
      pos 4329
      pos 4382
      pos 4604
      pos 5067
      pos 5085
      pos 5191
      pos 5402
      pos 5463
      pos 5616
      pos 5641
      pos 6602
      pos 6700
  term delta
    doc 13
      freq 4
      pos 5632
      pos 5848
      pos 5888
      pos 6229
  term demand
    doc 7
      freq 2
      pos 2516
      pos 2701
    doc 13
      freq 2
      pos 95
      pos 4328
    doc 15
      freq 1
      pos 2322
    doc 18
      freq 7
      pos 123
      pos 350
      pos 598
      pos 1642
      pos 1654
      pos 1700
      pos 1720
  term demanding
    doc 18
      freq 1
      pos 1695
  term demichelis
    doc 6
      freq 1
      pos 3009
  term demonstrated
    doc 2
      freq 1
      pos 1113
  term demonstrates
    doc 16
      freq 5
      pos 1746
      pos 1867
      pos 2125
      pos 2262
      pos 2287
  term demos
    doc 13
      freq 1
      pos 3565
  term demultiplexer
    doc 1
      freq 2
      pos 1089
      pos 1091
    doc 3
      freq 7
      pos 734
      pos 735
      pos 2186
      pos 2219
      pos 2259
      pos 2287
      pos 4208
  term demultiplexing
    doc 3
      freq 1
      pos 1004
  term demultiplexor
    doc 1
      freq 7
      pos 472
      pos 483
      pos 506
      pos 639
      pos 789
      pos 849
      pos 1461
  term denial
    doc 1
      freq 1
      pos 8023
    doc 4
      freq 4
      pos 4359
      pos 4414
      pos 4467
      pos 4547
    doc 5
      freq 3
      pos 314
      pos 3282
      pos 3459
    doc 13
      freq 2
      pos 325
      pos 6361
    doc 14
      freq 4
      pos 105
      pos 1213
      pos 2738
      pos 5296
    doc 18
      freq 2
      pos 480
      pos 1708
  term denis
    doc 11
      freq 2
      pos 9595
      pos 9597
    doc 17
      freq 1
      pos 2384
  term denis.pinkas
    doc 17
      freq 1
      pos 2397
  term denot
    doc 1
      freq 1
      pos 5400
  term deny
    doc 0
      freq 2
      pos 16021
      pos 16453
  term denying
    doc 18
      freq 3
      pos 917
      pos 992
      pos 1002
  term department
    doc 0
      freq 2
      pos 1107
      pos 17199
    doc 2
      freq 1
      pos 2861
    doc 11
      freq 1
      pos 10589
  term depend
    doc 1
      freq 2
      pos 2174
      pos 4666
    doc 2
      freq 1
      pos 1383
    doc 4
      freq 2
      pos 1998
      pos 4694
    doc 13
      freq 1
      pos 5090
    doc 18
      freq 1
      pos 1591
  term depended
    doc 2
      freq 2
      pos 5650
      pos 5697
  term dependencies
    doc 2
      freq 3
      pos 5315
      pos 5596
      pos 5705
  term dependency
    doc 7
      freq 1
      pos 681
  term dependent
    doc 2
      freq 1
      pos 4943
    doc 5
      freq 2
      pos 1087
      pos 2480
    doc 13
      freq 1
      pos 5459
  term depending
    doc 3
      freq 2
      pos 2728
      pos 3418
    doc 4
      freq 1
      pos 4667
    doc 5
      freq 1
      pos 3474
    doc 11
      freq 2
      pos 2518
      pos 7720
    doc 12
      freq 3
      pos 4482
      pos 5906
      pos 9310
    doc 13
      freq 3
      pos 4893
      pos 4936
      pos 6672
    doc 15
      freq 1
      pos 1176
  term depends
    doc 0
      freq 1
      pos 16355
    doc 1
      freq 4
      pos 3574
      pos 3877
      pos 6769
      pos 8379
    doc 3
      freq 3
      pos 2222
      pos 2237
      pos 5637
    doc 4
      freq 1
      pos 648
    doc 5
      freq 1
      pos 2754
    doc 9
      freq 1
      pos 829
    doc 10
      freq 1
      pos 2744
    doc 18
      freq 1
      pos 1796
    skipList 
      level 0
        skipDoc 18
        skipDocFP 719683
        impacts 
          impact 
            freq 1
            norm 95
          impact 
            freq 3
            norm 107
          impact 
            freq 4
            norm 113
        impactsEnd 
  term deploy
    doc 0
      freq 1
      pos 16814
    doc 1
      freq 1
      pos 8737
    doc 12
      freq 1
      pos 5290
  term deployabl
    doc 13
      freq 1
      pos 1806
  term deployed
    doc 1
      freq 1
      pos 8055
    doc 3
      freq 1
      pos 3532
    doc 4
      freq 1
      pos 2007
    doc 6
      freq 1
      pos 140
    doc 7
      freq 1
      pos 1760
    doc 12
      freq 4
      pos 1481
      pos 2404
      pos 5480
      pos 6895
  term deployment
    doc 0
      freq 1
      pos 16799
    doc 6
      freq 1
      pos 168
    doc 10
      freq 3
      pos 1529
      pos 10268
      pos 10429
    doc 12
      freq 2
      pos 4485
      pos 7956
    doc 13
      freq 3
      pos 4703
      pos 4939
      pos 5466
    doc 14
      freq 1
      pos 297
    doc 15
      freq 3
      pos 1365
      pos 3273
      pos 3657
  term deployments
    doc 6
      freq 1
      pos 876
    doc 10
      freq 2
      pos 4323
      pos 7417
    doc 12
      freq 1
      pos 1817
    doc 13
      freq 1
      pos 5107
    doc 15
      freq 2
      pos 423
      pos 1108
  term deploys
    doc 10
      freq 1
      pos 10536
  term deprecat
    doc 7
      freq 1
      pos 1491
  term deprecated
    doc 2
      freq 1
      pos 2427
    doc 12
      freq 2
      pos 1283
      pos 7908
  term deprecating
    doc 12
      freq 1
      pos 7320
  term deprecation
    doc 7
      freq 3
      pos 1339
      pos 1364
      pos 1406
  term dept
    doc 13
      freq 1
      pos 7059
  term depth
    doc 12
      freq 1
      pos 3947
  term depths
    doc 6
      freq 1
      pos 923
  term dereferenced
    doc 10
      freq 2
      pos 4054
      pos 11671
  term dereferences
    doc 10
      freq 2
      pos 5579
      pos 6727
  term dereferencing
    doc 10
      freq 2
      pos 4023
      pos 6772
  term derek
    doc 11
      freq 1
      pos 9439
  term deriv
    doc 5
      freq 4
      pos 1225
      pos 1241
      pos 3116
      pos 3528
    doc 6
      freq 1
      pos 536
    doc 14
      freq 4
      pos 693
      pos 908
      pos 1387
      pos 1564
  term derivation
    doc 0
      freq 1
      pos 2417
    doc 14
      freq 17
      pos 16
      pos 136
      pos 143
      pos 154
      pos 161
      pos 398
      pos 687
      pos 902
      pos 1194
      pos 1245
      pos 1286
      pos 1332
      pos 1344
      pos 1381
      pos 1558
      pos 2227
      pos 5278
  term derivations
    doc 14
      freq 5
      pos 129
      pos 619
      pos 621
      pos 656
      pos 1949
  term derived
    doc 0
      freq 1
      pos 346
    doc 1
      freq 1
      pos 1004
    doc 2
      freq 1
      pos 3831
    doc 3
      freq 1
      pos 562
    doc 4
      freq 1
      pos 5454
    doc 14
      freq 2
      pos 1279
      pos 1319
    doc 18
      freq 1
      pos 1826
  term deriving
    doc 6
      freq 1
      pos 1889
    doc 14
      freq 2
      pos 75
      pos 2395
  term des
    doc 7
      freq 2
      pos 1139
      pos 2728
    doc 13
      freq 8
      pos 5131
      pos 5188
      pos 5254
      pos 5390
      pos 5484
      pos 5523
      pos 5540
      pos 5592
  term describ
    doc 0
      freq 2
      pos 206
      pos 15536
    doc 1
      freq 1
      pos 998
    doc 3
      freq 1
      pos 556
    doc 4
      freq 3
      pos 338
      pos 983
      pos 2060
    doc 6
      freq 2
      pos 526
      pos 624
    doc 10
      freq 1
      pos 10909
    doc 12
      freq 2
      pos 700
      pos 8688
    doc 13
      freq 10
      pos 618
      pos 1053
      pos 1226
      pos 1917
      pos 1997
      pos 2887
      pos 3198
      pos 3424
      pos 3495
      pos 5562
    skipList 
      level 0
        skipDoc 13
        skipDocFP 723531
        impacts 
          impact 
            freq 2
            norm 101
          impact 
            freq 3
            norm 108
          impact 
            freq 10
            norm 109
        impactsEnd 
  term described
    doc 0
      freq 9
      pos 281
      pos 320
      pos 337
      pos 435
      pos 448
      pos 981
      pos 1136
      pos 1152
      pos 17366
    doc 1
      freq 9
      pos 1183
      pos 1970
      pos 2064
      pos 2079
      pos 3021
      pos 3045
      pos 5002
      pos 8629
      pos 9747
    doc 2
      freq 7
      pos 526
      pos 537
      pos 706
      pos 1391
      pos 1898
      pos 2135
      pos 6544
    doc 3
      freq 11
      pos 404
      pos 413
      pos 422
      pos 827
      pos 1258
      pos 1459
      pos 3039
      pos 4031
      pos 4125
      pos 4239
      pos 6096
    doc 4
      freq 3
      pos 355
      pos 467
      pos 6251
    doc 5
      freq 15
      pos 871
      pos 953
      pos 994
      pos 1071
      pos 2001
      pos 2062
      pos 2309
      pos 2385
      pos 2785
      pos 2883
      pos 3008
      pos 3260
      pos 3425
      pos 3725
      pos 4581
    doc 6
      freq 6
      pos 646
      pos 697
      pos 772
      pos 889
      pos 2818
      pos 3381
    doc 7
      freq 2
      pos 1562
      pos 3086
    doc 8
      freq 3
      pos 331
      pos 343
      pos 2303
    doc 9
      freq 3
      pos 368
      pos 446
      pos 1948
    doc 10
      freq 27
      pos 647
      pos 698
      pos 857
      pos 1790
      pos 2621
      pos 4159
      pos 4212
      pos 4260
      pos 4277
      pos 4478
      pos 5519
      pos 5637
      pos 7431
      pos 7785
      pos 7980
      pos 8191
      pos 8484
      pos 9052
      pos 9745
      pos 10777
      pos 11565
      pos 11653
      pos 11747
      pos 11860
      pos 12073
      pos 12852
      pos 13609
    doc 11
      freq 2
      pos 605
      pos 10770
    doc 12
      freq 14
      pos 623
      pos 898
      pos 1393
      pos 2139
      pos 3167
      pos 3501
      pos 4142
      pos 4678
      pos 5172
      pos 5280
      pos 5455
      pos 6348
      pos 9035
      pos 9620
    doc 13
      freq 6
      pos 422
      pos 690
      pos 808
      pos 1207
      pos 2466
      pos 7235
    doc 14
      freq 5
      pos 309
      pos 413
      pos 1335
      pos 1950
      pos 5701
    doc 15
      freq 1
      pos 4220
    doc 16
      freq 6
      pos 253
      pos 261
      pos 667
      pos 711
      pos 1178
      pos 2831
    doc 17
      freq 2
      pos 291
      pos 2555
    doc 18
      freq 7
      pos 406
      pos 955
      pos 1171
      pos 1261
      pos 1898
      pos 1968
      pos 2343
    skipList 
      level 0
        skipDoc 7
        skipDocFP 724343
        impacts 
          impact 
            freq 2
            norm 100
          impact 
            freq 6
            norm 101
          impact 
            freq 15
            norm 104
        impactsEnd 
        skipDoc 15
        skipDocFP 725438
        impacts 
          impact 
            freq 3
            norm 95
          impact 
            freq 5
            norm 107
          impact 
            freq 6
            norm 109
          impact 
            freq 14
            norm 113
          impact 
            freq 27
            norm 116
        impactsEnd 
  term describes
    doc 0
      freq 10
      pos 113
      pos 303
      pos 1124
      pos 4682
      pos 4749
      pos 6395
      pos 7300
      pos 12080
      pos 12856
      pos 13034
    doc 1
      freq 2
      pos 651
      pos 671
    doc 2
      freq 2
      pos 88
      pos 305
    doc 3
      freq 2
      pos 859
      pos 5433
    doc 4
      freq 3
      pos 104
      pos 323
      pos 4072
    doc 5
      freq 8
      pos 499
      pos 768
      pos 817
      pos 835
      pos 877
      pos 1520
      pos 2764
      pos 3762
    doc 10
      freq 4
      pos 1344
      pos 8216
      pos 11957
      pos 12040
    doc 12
      freq 2
      pos 648
      pos 6497
    doc 13
      freq 2
      pos 1282
      pos 3871
    doc 14
      freq 2
      pos 71
      pos 429
    doc 15
      freq 1
      pos 130
    doc 16
      freq 2
      pos 852
      pos 1241
    doc 17
      freq 1
      pos 86
    doc 18
      freq 1
      pos 95
    skipList 
      level 0
        skipDoc 12
        skipDocFP 727501
        impacts 
          impact 
            freq 8
            norm 104
          impact 
            freq 10
            norm 120
        impactsEnd 
  term describing
    doc 0
      freq 2
      pos 11744
      pos 17025
    doc 1
      freq 1
      pos 6236
    doc 2
      freq 2
      pos 845
      pos 5943
    doc 5
      freq 2
      pos 521
      pos 1116
    doc 7
      freq 1
      pos 1164
    doc 10
      freq 1
      pos 10440
    doc 13
      freq 5
      pos 1603
      pos 2916
      pos 3548
      pos 3735
      pos 6178
  term description
    doc 0
      freq 314
      pos 1121
      pos 1240
      pos 1414
      pos 1437
      pos 1501
      pos 1586
      pos 1621
      pos 1638
      pos 1660
      pos 1708
      pos 1753
      pos 1804
      pos 1831
      pos 1857
      pos 1888
      pos 1926
      pos 1954
      pos 1975
      pos 2001
      pos 2028
      pos 2063
      pos 2297
      pos 2340
      pos 2393
      pos 2475
      pos 2552
      pos 2621
      pos 2673
      pos 2731
      pos 2778
      pos 2816
      pos 2864
      pos 2957
      pos 2983
      pos 3044
      pos 3143
      pos 3184
      pos 3240
      pos 3361
      pos 3415
      pos 3475
      pos 3530
      pos 3598
      pos 3703
      pos 3726
      pos 3780
      pos 3889
      pos 3932
      pos 3962
      pos 4024
      pos 4106
      pos 4215
      pos 4238
      pos 4292
      pos 4389
      pos 4465
      pos 4486
      pos 4533
      pos 4566
      pos 4592
      pos 4619
      pos 4659
      pos 4679
      pos 4743
      pos 4763
      pos 4832
      pos 4872
      pos 4971
      pos 5048
      pos 5148
      pos 5177
      pos 5207
      pos 5248
      pos 5417
      pos 5440
      pos 5520
      pos 5599
      pos 5632
      pos 5654
      pos 5738
      pos 5797
      pos 5834
      pos 5911
      pos 5962
      pos 6027
      pos 6087
      pos 6141
      pos 6197
      pos 6221
      pos 6283
      pos 6306
      pos 6389
      pos 6409
      pos 6450
      pos 6476
      pos 6510
      pos 6618
      pos 6728
      pos 6789
      pos 6848
      pos 6942
      pos 6989
      pos 7029
      pos 7107
      pos 7164
      pos 7212
      pos 7233
      pos 7294
      pos 7321
      pos 7394
      pos 7427
      pos 7452
      pos 7479
      pos 7521
      pos 7552
      pos 7579
      pos 7623
      pos 7662
      pos 7690
      pos 7723
      pos 7759
      pos 7780
      pos 7851
      pos 7906
      pos 7937
      pos 7974
      pos 8015
      pos 8054
      pos 8095
      pos 8149
      pos 8186
      pos 8220
      pos 8279
      pos 8308
      pos 8373
      pos 8401
      pos 8448
      pos 8516
      pos 8574
      pos 8632
      pos 8689
      pos 8734
      pos 8776
      pos 8835
      pos 8856
      pos 8933
      pos 8983
      pos 9014
      pos 9059
      pos 9104
      pos 9128
      pos 9154
      pos 9184
      pos 9258
      pos 9298
      pos 9328
      pos 9407
      pos 9455
      pos 9506
      pos 9538
      pos 9606
      pos 9638
      pos 9691
      pos 9720
      pos 9761
      pos 9831
      pos 9863
      pos 9923
      pos 9981
      pos 10005
      pos 10081
      pos 10114
      pos 10163
      pos 10204
      pos 10249
      pos 10476
      pos 10513
      pos 10547
      pos 10623
      pos 10721
      pos 10821
      pos 10895
      pos 10928
      pos 11079
      pos 11112
      pos 11157
      pos 11255
      pos 11286
      pos 11320
      pos 11359
      pos 11411
      pos 11462
      pos 11506
      pos 11539
      pos 11569
      pos 11603
      pos 11679
      pos 11719
      pos 11738
      pos 11807
      pos 11828
      pos 11852
      pos 11872
      pos 11906
      pos 11930
      pos 11952
      pos 11971
      pos 12056
      pos 12077
      pos 12134
      pos 12183
      pos 12203
      pos 12225
      pos 12244
      pos 12267
      pos 12321
      pos 12344
      pos 12368
      pos 12393
      pos 12421
      pos 12446
      pos 12484
      pos 12510
      pos 12540
      pos 12584
      pos 12611
      pos 12659
      pos 12680
      pos 12735
      pos 12756
      pos 12794
      pos 12833
      pos 12926
      pos 13007
      pos 13080
      pos 13194
      pos 13283
      pos 13347
      pos 13414
      pos 13500
      pos 13599
      pos 13689
      pos 13792
      pos 13866
      pos 13951
      pos 14079
      pos 14207
      pos 14258
      pos 14389
      pos 14445
      pos 14454
      pos 14478
      pos 14514
      pos 14554
      pos 14611
      pos 14620
      pos 14644
      pos 14680
      pos 14704
      pos 14728
      pos 14765
      pos 14828
      pos 14840
      pos 14852
      pos 14864
      pos 14876
      pos 14888
      pos 14900
      pos 14912
      pos 14936
      pos 14948
      pos 14960
      pos 14972
      pos 14984
      pos 14996
      pos 15008
      pos 15020
      pos 15032
      pos 15044
      pos 15068
      pos 15080
      pos 15092
      pos 15104
      pos 15116
      pos 15128
      pos 15140
      pos 15152
      pos 15164
      pos 15188
      pos 15200
      pos 15212
      pos 15224
      pos 15236
      pos 15248
      pos 15260
      pos 15272
      pos 15284
      pos 15296
      pos 15320
      pos 15332
      pos 15344
      pos 15356
      pos 15368
      pos 15380
      pos 15392
      pos 15461
      pos 15529
      pos 15575
      pos 15610
      pos 15656
      pos 15680
      pos 15708
      pos 15750
      pos 15780
    doc 1
      freq 6
      pos 4055
      pos 6215
      pos 6225
      pos 6255
      pos 7779
      pos 7830
    doc 4
      freq 8
      pos 2226
      pos 2856
      pos 3113
      pos 3375
      pos 3660
      pos 3826
      pos 5643
      pos 5681
    doc 5
      freq 5
      pos 655
      pos 2902
      pos 3839
      pos 3869
      pos 4309
    doc 8
      freq 12
      pos 415
      pos 584
      pos 628
      pos 920
      pos 1009
      pos 1034
      pos 1245
      pos 1303
      pos 1426
      pos 1498
      pos 1567
      pos 1584
    doc 10
      freq 1
      pos 9091
    doc 11
      freq 2
      pos 601
      pos 9667
    doc 12
      freq 2
      pos 469
      pos 8114
    doc 13
      freq 13
      pos 426
      pos 612
      pos 1590
      pos 1948
      pos 1977
      pos 3367
      pos 3528
      pos 4408
      pos 5209
      pos 5447
      pos 5599
      pos 6765
      pos 6819
    skipList 
      level 0
        skipDoc 12
        skipDocFP 729079
        impacts 
          impact 
            freq 12
            norm 97
          impact 
            freq 314
            norm 120
        impactsEnd 
  term descriptions
    doc 13
      freq 20
      pos 303
      pos 405
      pos 440
      pos 462
      pos 493
      pos 494
      pos 565
      pos 589
      pos 602
      pos 651
      pos 1094
      pos 1131
      pos 1644
      pos 1699
      pos 1722
      pos 1765
      pos 1874
      pos 2983
      pos 4595
      pos 5129
  term descriptiv
    doc 13
      freq 1
      pos 1616
  term descriptor
    doc 0
      freq 1
      pos 15829
  term descriptors
    doc 10
      freq 1
      pos 9128
  term deserv
    doc 12
      freq 1
      pos 1661
    doc 13
      freq 1
      pos 6046
  term deserves
    doc 11
      freq 1
      pos 1363
  term design
    doc 0
      freq 1
      pos 16354
    doc 1
      freq 2
      pos 5587
      pos 7268
    doc 3
      freq 1
      pos 409
    doc 9
      freq 1
      pos 1756
    doc 10
      freq 3
      pos 9566
      pos 9987
      pos 10700
    doc 11
      freq 2
      pos 9340
      pos 9580
    doc 12
      freq 1
      pos 1447
    doc 13
      freq 2
      pos 2118
      pos 3992
    doc 18
      freq 1
      pos 2002
    skipList 
      level 0
        skipDoc 13
        skipDocFP 735770
        impacts 
          impact 
            freq 1
            norm 95
          impact 
            freq 2
            norm 109
          impact 
            freq 3
            norm 116
        impactsEnd 
  term designated
    doc 0
      freq 11
      pos 1482
      pos 6483
      pos 6583
      pos 6602
      pos 6734
      pos 6755
      pos 6957
      pos 7130
      pos 8226
      pos 9308
      pos 16589
    doc 5
      freq 2
      pos 3800
      pos 4016
    doc 10
      freq 2
      pos 3527
      pos 11687
  term designation
    doc 11
      freq 1
      pos 6131
  term designed
    doc 0
      freq 1
      pos 2872
    doc 11
      freq 2
      pos 87
      pos 9365
    doc 12
      freq 1
      pos 882
    doc 13
      freq 2
      pos 102
      pos 4658
    doc 15
      freq 2
      pos 113
      pos 357
  term designing
    doc 13
      freq 1
      pos 3697
  term desir
    doc 9
      freq 1
      pos 476
    doc 16
      freq 1
      pos 386
  term desirabl
    doc 5
      freq 1
      pos 3608
    doc 10
      freq 2
      pos 586
      pos 9040
    doc 12
      freq 3
      pos 1427
      pos 3844
      pos 5154
    doc 14
      freq 1
      pos 2093
    doc 15
      freq 2
      pos 1621
      pos 3556
  term desired
    doc 1
      freq 1
      pos 1194
    doc 5
      freq 2
      pos 2863
      pos 2924
    doc 12
      freq 1
      pos 8008
  term desires
    doc 12
      freq 1
      pos 3695
  term despit
    doc 2
      freq 1
      pos 5592
    doc 11
      freq 1
      pos 7346
  term destination
    doc 0
      freq 14
      pos 10206
      pos 10332
      pos 10407
      pos 10431
      pos 10441
      pos 10563
      pos 10636
      pos 10757
      pos 11114
      pos 11272
      pos 11327
      pos 11514
      pos 11578
      pos 11619
    doc 3
      freq 2
      pos 455
      pos 2898
    doc 4
      freq 46
      pos 187
      pos 764
      pos 1076
      pos 1219
      pos 1247
      pos 1388
      pos 2089
      pos 2151
      pos 2172
      pos 2176
      pos 2202
      pos 2228
      pos 2257
      pos 2372
      pos 2407
      pos 2423
      pos 2433
      pos 2476
      pos 2497
      pos 2559
      pos 2564
      pos 2644
      pos 2698
      pos 2733
      pos 2817
      pos 2943
      pos 3062
      pos 3298
      pos 3591
      pos 3762
      pos 3887
      pos 4200
      pos 4245
      pos 4271
      pos 4433
      pos 4452
      pos 4537
      pos 4555
      pos 5074
      pos 5105
      pos 5118
      pos 5645
      pos 5669
      pos 5706
      pos 5713
      pos 5971
    doc 10
      freq 1
      pos 578
  term destinations
    doc 4
      freq 1
      pos 4564
    doc 10
      freq 1
      pos 598
  term destined
    doc 4
      freq 2
      pos 1664
      pos 2522
  term destroy
    doc 0
      freq 2
      pos 3279
      pos 5683
  term destroying
    doc 18
      freq 1
      pos 1837
  term detail
    doc 4
      freq 1
      pos 4080
    doc 5
      freq 1
      pos 3767
    doc 6
      freq 1
      pos 1691
    doc 13
      freq 2
      pos 1561
      pos 1892
  term detailed
    doc 0
      freq 1
      pos 200
    doc 1
      freq 2
      pos 4054
      pos 4693
    doc 8
      freq 1
      pos 95
    doc 10
      freq 2
      pos 5555
      pos 12142
    doc 11
      freq 1
      pos 9425
    doc 13
      freq 1
      pos 2787
    doc 14
      freq 1
      pos 1183
    doc 15
      freq 1
      pos 1675
    doc 17
      freq 1
      pos 1272
    skipList 
      level 0
        skipDoc 15
        skipDocFP 739358
        impacts 
          impact 
            freq 1
            norm 97
          impact 
            freq 2
            norm 113
        impactsEnd 
  term details
    doc 1
      freq 4
      pos 228
      pos 1975
      pos 3301
      pos 7387
    doc 2
      freq 1
      pos 325
    doc 3
      freq 5
      pos 192
      pos 308
      pos 1688
      pos 4024
      pos 5428
    doc 4
      freq 1
      pos 905
    doc 5
      freq 3
      pos 571
      pos 1640
      pos 2810
    doc 10
      freq 2
      pos 3353
      pos 8317
    doc 11
      freq 49
      pos 1447
      pos 1905
      pos 2192
      pos 2355
      pos 2551
      pos 2672
      pos 2792
      pos 3327
      pos 3505
      pos 3611
      pos 3769
      pos 3992
      pos 4125
      pos 4269
      pos 4445
      pos 4661
      pos 4899
      pos 5018
      pos 5149
      pos 5310
      pos 5450
      pos 5616
      pos 5782
      pos 5926
      pos 6151
      pos 6342
      pos 6432
      pos 6594
      pos 6671
      pos 6761
      pos 6853
      pos 6961
      pos 7098
      pos 7205
      pos 7375
      pos 7504
      pos 7634
      pos 7731
      pos 7844
      pos 8036
      pos 8120
      pos 8313
      pos 8465
      pos 8599
      pos 8723
      pos 8813
      pos 8912
      pos 9062
      pos 9242
    doc 13
      freq 1
      pos 3501
    doc 14
      freq 1
      pos 1858
    skipList 
      level 0
        skipDoc 13
        skipDocFP 739973
        impacts 
          impact 
            freq 3
            norm 104
          impact 
            freq 5
            norm 107
          impact 
            freq 49
            norm 114
        impactsEnd 
  term detect
    doc 3
      freq 1
      pos 1644
    doc 4
      freq 1
      pos 670
    doc 5
      freq 1
      pos 3382
    doc 6
      freq 1
      pos 1013
  term detected
    doc 0
      freq 1
      pos 7328
    doc 3
      freq 2
      pos 1572
      pos 3069
    doc 4
      freq 2
      pos 3344
      pos 3469
    doc 6
      freq 2
      pos 2378
      pos 2741
    doc 10
      freq 1
      pos 9738
    doc 17
      freq 1
      pos 1445
  term detecting
    doc 15
      freq 1
      pos 3740
  term detection
    doc 0
      freq 2
      pos 16234
      pos 16518
    doc 2
      freq 1
      pos 2605
    doc 3
      freq 2
      pos 4436
      pos 4480
    doc 6
      freq 1
      pos 2463
  term detects
    doc 3
      freq 2
      pos 1789
      pos 1867
  term deterioration
    doc 6
      freq 1
      pos 2483
  term determin
    doc 1
      freq 2
      pos 1354
      pos 1421
    doc 3
      freq 1
      pos 3373
    doc 4
      freq 1
      pos 1071
    doc 5
      freq 1
      pos 2172
    doc 6
      freq 1
      pos 2839
    doc 7
      freq 2
      pos 183
      pos 320
    doc 10
      freq 6
      pos 1179
      pos 2426
      pos 2526
      pos 4164
      pos 7733
      pos 11279
    doc 11
      freq 1
      pos 7334
    doc 12
      freq 1
      pos 8180
    doc 15
      freq 2
      pos 3281
      pos 3697
    doc 17
      freq 2
      pos 744
      pos 1374
    skipList 
      level 0
        skipDoc 11
        skipDocFP 742324
        impacts 
          impact 
            freq 2
            norm 100
          impact 
            freq 6
            norm 116
        impactsEnd 
  term determination
    doc 4
      freq 2
      pos 169
      pos 1061
    doc 5
      freq 2
      pos 1174
      pos 2538
  term determined
    doc 0
      freq 7
      pos 3750
      pos 3759
      pos 4253
      pos 4276
      pos 9780
      pos 11136
      pos 11334
    doc 1
      freq 2
      pos 5939
      pos 8745
    doc 2
      freq 1
      pos 5996
    doc 3
      freq 2
      pos 2267
      pos 2475
    doc 5
      freq 1
      pos 1446
    doc 6
      freq 1
      pos 641
    doc 9
      freq 1
      pos 1193
    doc 13
      freq 1
      pos 5351
    skipList 
      level 0
        skipDoc 13
        skipDocFP 743249
        impacts 
          impact 
            freq 1
            norm 95
          impact 
            freq 2
            norm 107
          impact 
            freq 7
            norm 120
        impactsEnd 
  term determines
    doc 3
      freq 1
      pos 4265
    doc 4
      freq 1
      pos 638
    doc 10
      freq 2
      pos 2450
      pos 4219
  term determining
    doc 3
      freq 1
      pos 3802
    doc 5
      freq 4
      pos 1269
      pos 1311
      pos 1364
      pos 1437
    doc 6
      freq 1
      pos 1896
    doc 10
      freq 2
      pos 800
      pos 1014
    doc 14
      freq 1
      pos 1912
  term devanatham
    doc 11
      freq 1
      pos 9569
  term develop
    doc 2
      freq 3
      pos 2143
      pos 4391
      pos 4409
    doc 7
      freq 1
      pos 1370
    doc 15
      freq 1
      pos 3675
  term developed
    doc 2
      freq 8
      pos 95
      pos 1224
      pos 1239
      pos 3521
      pos 3964
      pos 4010
      pos 4613
      pos 6228
    doc 7
      freq 1
      pos 192
    doc 11
      freq 1
      pos 611
  term developers
    doc 2
      freq 1
      pos 4346
  term developing
    doc 2
      freq 3
      pos 1396
      pos 2072
      pos 4495
    doc 6
      freq 1
      pos 2497
  term development
    doc 2
      freq 17
      pos 71
      pos 173
      pos 220
      pos 1120
      pos 2110
      pos 3501
      pos 4127
      pos 4307
      pos 4319
      pos 4337
      pos 4423
      pos 4441
      pos 4922
      pos 4958
      pos 5032
      pos 6046
      pos 6059
    doc 6
      freq 1
      pos 311
    doc 8
      freq 1
      pos 298
    doc 9
      freq 1
      pos 539
    doc 10
      freq 1
      pos 12848
    doc 11
      freq 1
      pos 9557
    doc 12
      freq 3
      pos 4011
      pos 4036
      pos 4058
    doc 13
      freq 1
      pos 107
    skipList 
      level 0
        skipDoc 13
        skipDocFP 745023
        impacts 
          impact 
            freq 1
            norm 95
          impact 
            freq 17
            norm 108
        impactsEnd 
  term deviat
    doc 2
      freq 1
      pos 3805
  term deviation
    doc 6
      freq 2
      pos 234
      pos 1540
  term deviations
    doc 6
      freq 2
      pos 980
      pos 2330
    doc 18
      freq 1
      pos 913
  term devic
    doc 0
      freq 1
      pos 14790
    doc 3
      freq 3
      pos 3096
      pos 5343
      pos 5372
    doc 4
      freq 1
      pos 2024
    doc 6
      freq 3
      pos 868
      pos 2325
      pos 2737
  term devices
    doc 1
      freq 2
      pos 5030
      pos 8149
    doc 2
      freq 1
      pos 2935
    doc 3
      freq 1
      pos 3886
    doc 6
      freq 2
      pos 961
      pos 2139
    doc 10
      freq 3
      pos 1707
      pos 1724
      pos 1745
    doc 13
      freq 3
      pos 893
      pos 1020
      pos 4933
    doc 15
      freq 1
      pos 3365
  term df
    doc 6
      freq 26
      pos 1154
      pos 1289
      pos 1312
      pos 1359
      pos 1362
      pos 1395
      pos 1518
      pos 1624
      pos 1657
      pos 1695
      pos 1908
      pos 1918
      pos 1946
      pos 2003
      pos 2174
      pos 2196
      pos 2217
      pos 2284
      pos 2355
      pos 2361
      pos 2416
      pos 2440
      pos 2478
      pos 2647
      pos 2677
      pos 2713
  term df:mlr
    doc 6
      freq 1
      pos 2172
  term dfcndsxvh
    doc 10
      freq 1
      pos 6233
  term dhc
    doc 15
      freq 3
      pos 1774
      pos 3600
      pos 3792
  term dhcid
    doc 12
      freq 1
      pos 7835
  term dhcp
    doc 12
      freq 16
      pos 399
      pos 4571
      pos 4578
      pos 4593
      pos 4602
      pos 4654
      pos 4671
      pos 5952
      pos 5971
      pos 6071
      pos 6077
      pos 6154
      pos 7306
      pos 7815
      pos 7833
      pos 7871
    doc 15
      freq 79
      pos 29
      pos 105
      pos 110
      pos 137
      pos 194
      pos 246
      pos 260
      pos 305
      pos 322
      pos 342
      pos 351
      pos 469
      pos 511
      pos 534
      pos 542
      pos 576
      pos 583
      pos 635
      pos 692
      pos 715
      pos 723
      pos 775
      pos 799
      pos 833
      pos 881
      pos 956
      pos 981
      pos 1025
      pos 1081
      pos 1092
      pos 1141
      pos 1314
      pos 1393
      pos 1499
      pos 1521
      pos 1527
      pos 1555
      pos 1678
      pos 1697
      pos 1711
      pos 1743
      pos 1753
      pos 1782
      pos 1826
      pos 1834
      pos 1855
      pos 1910
      pos 1949
      pos 2148
      pos 2230
      pos 2266
      pos 2344
      pos 2368
      pos 2553
      pos 2594
      pos 2663
      pos 2767
      pos 2944
      pos 2989
      pos 3006
      pos 3144
      pos 3155
      pos 3190
      pos 3223
      pos 3237
      pos 3285
      pos 3307
      pos 3347
      pos 3376
      pos 3393
      pos 3407
      pos 3430
      pos 3547
      pos 3613
      pos 3802
      pos 3931
      pos 3970
      pos 4008
      pos 4071
  term dhcpv4
    doc 12
      freq 1
      pos 5954
    doc 15
      freq 18
      pos 159
      pos 1449
      pos 1876
      pos 2065
      pos 2102
      pos 2200
      pos 2433
      pos 2535
      pos 2642
      pos 2707
      pos 2751
      pos 2876
      pos 3167
      pos 3370
      pos 3467
      pos 3520
      pos 3575
      pos 3995
  term dhcpv6
    doc 12
      freq 12
      pos 3917
      pos 3970
      pos 3985
      pos 4004
      pos 4025
      pos 4049
      pos 4434
      pos 4474
      pos 5983
      pos 6058
      pos 7191
      pos 7293
    doc 15
      freq 59
      pos 123
      pos 161
      pos 265
      pos 361
      pos 408
      pos 546
      pos 552
      pos 589
      pos 699
      pos 758
      pos 883
      pos 950
      pos 983
      pos 1316
      pos 1532
      pos 1557
      pos 1573
      pos 1648
      pos 1680
      pos 1713
      pos 1738
      pos 1784
      pos 1812
      pos 1836
      pos 1878
      pos 1912
      pos 1951
      pos 2042
      pos 2054
      pos 2104
      pos 2203
      pos 2252
      pos 2268
      pos 2298
      pos 2313
      pos 2332
      pos 2352
      pos 2435
      pos 2530
      pos 2569
      pos 2604
      pos 2628
      pos 2732
      pos 2760
      pos 2882
      pos 2937
      pos 3149
      pos 3192
      pos 3213
      pos 3239
      pos 3272
      pos 3309
      pos 3319
      pos 3433
      pos 3469
      pos 3522
      pos 3615
      pos 3660
      pos 3957
  term dhct9gp
    doc 10
      freq 1
      pos 6838
  term dhhmac
    doc 5
      freq 2
      pos 815
      pos 4241
  term dhiruba
    doc 3
      freq 1
      pos 4800
  term dhkcpk7qxql6oeehj
    doc 11
      freq 1
      pos 10149
  term dhpgwboecplygxkrtajv8feshnmnaezbqkrjewox
    doc 10
      freq 1
      pos 12662
  term dhtjezuhjpmnp7hongomeyfukmgc
    doc 11
      freq 1
      pos 10016
  term dhwbqws4lry57phdceryrjr96aztb91l5
    doc 11
      freq 1
      pos 9882
  term diagnos
    doc 6
      freq 1
      pos 455
  term diagnostic
    doc 4
      freq 2
      pos 3697
      pos 3863
    doc 6
      freq 2
      pos 191
      pos 1382
  term diagnostics
    doc 4
      freq 1
      pos 498
    doc 9
      freq 1
      pos 542
  term diagram
    doc 1
      freq 4
      pos 418
      pos 5680
      pos 7082
      pos 9414
    doc 3
      freq 3
      pos 912
      pos 930
      pos 3677
  term dial
    doc 2
      freq 4
      pos 3028
      pos 3127
      pos 3144
      pos 3174
    doc 13
      freq 4
      pos 183
      pos 2430
      pos 2434
      pos 2534
  term dialog
    doc 10
      freq 13
      pos 204
      pos 3392
      pos 3468
      pos 3496
      pos 3543
      pos 3562
      pos 3694
      pos 3720
      pos 3736
      pos 4587
      pos 4605
      pos 6933
      pos 8806
  term dictat
    doc 10
      freq 1
      pos 3160
  term dictionary
    doc 9
      freq 1
      pos 1129
  term did
    doc 0
      freq 1
      pos 16752
    doc 2
      freq 1
      pos 4569
    doc 4
      freq 1
      pos 3990
    doc 5
      freq 1
      pos 3086
    doc 6
      freq 2
      pos 1954
      pos 2122
    doc 12
      freq 1
      pos 842
    doc 18
      freq 1
      pos 833
  term diego
    doc 11
      freq 1
      pos 9433
    doc 16
      freq 1
      pos 2659
  term diff
    doc 5
      freq 3
      pos 795
      pos 821
      pos 4246
  term differ
    doc 0
      freq 1
      pos 6593
    doc 12
      freq 2
      pos 8510
      pos 9208
  term differenc
    doc 6
      freq 2
      pos 1170
      pos 2285
    doc 12
      freq 2
      pos 3073
      pos 9196
  term differences
    doc 10
      freq 1
      pos 10883
    doc 13
      freq 3
      pos 4962
      pos 5601
      pos 5624
    doc 15
      freq 4
      pos 2165
      pos 2171
      pos 3188
      pos 3253
  term different
    doc 0
      freq 11
      pos 2925
      pos 7633
      pos 8069
      pos 8111
      pos 8164
      pos 10679
      pos 13091
      pos 13205
      pos 13358
      pos 13614
      pos 16425
    doc 1
      freq 7
      pos 3322
      pos 3326
      pos 3331
      pos 3449
      pos 4200
      pos 7617
      pos 8183
    doc 3
      freq 9
      pos 2390
      pos 3463
      pos 4058
      pos 5473
      pos 5516
      pos 5522
      pos 5532
      pos 5829
      pos 5833
    doc 4
      freq 3
      pos 568
      pos 4150
      pos 4201
    doc 5
      freq 3
      pos 416
      pos 848
      pos 3303
    doc 7
      freq 1
      pos 1556
    doc 8
      freq 1
      pos 957
    doc 9
      freq 2
      pos 1152
      pos 1176
    doc 10
      freq 5
      pos 3193
      pos 3422
      pos 8069
      pos 8438
      pos 9659
    doc 11
      freq 1
      pos 987
    doc 12
      freq 12
      pos 2012
      pos 2051
      pos 2329
      pos 2343
      pos 2347
      pos 2393
      pos 2807
      pos 2813
      pos 3846
      pos 5628
      pos 5877
      pos 9165
    doc 13
      freq 21
      pos 712
      pos 721
      pos 892
      pos 967
      pos 1398
      pos 1889
      pos 1894
      pos 3136
      pos 3141
      pos 3149
      pos 3184
      pos 3636
      pos 3643
      pos 3679
      pos 5310
      pos 6164
      pos 6173
      pos 6242
      pos 6245
      pos 6691
      pos 6694
    doc 15
      freq 16
      pos 221
      pos 1103
      pos 1147
      pos 1173
      pos 1217
      pos 1279
      pos 1306
      pos 1309
      pos 1313
      pos 1562
      pos 1942
      pos 2129
      pos 2859
      pos 2863
      pos 2892
      pos 3205
    doc 17
      freq 1
      pos 1546
    skipList 
      level 0
        skipDoc 9
        skipDocFP 752585
        impacts 
          impact 
            freq 2
            norm 95
          impact 
            freq 3
            norm 104
          impact 
            freq 9
            norm 107
          impact 
            freq 11
            norm 120
        impactsEnd 
  term differentiat
    doc 10
      freq 1
      pos 4648
  term differentiated
    doc 0
      freq 1
      pos 17007
  term differs
    doc 14
      freq 1
      pos 1178
  term difficult
    doc 1
      freq 1
      pos 8735
    doc 2
      freq 3
      pos 1182
      pos 4179
      pos 4793
    doc 5
      freq 1
      pos 3621
    doc 6
      freq 1
      pos 608
    doc 10
      freq 2
      pos 9677
      pos 10257
    doc 12
      freq 8
      pos 4931
      pos 5451
      pos 5716
      pos 6048
      pos 6361
      pos 6490
      pos 6579
      pos 9406
  term difficulties
    doc 2
      freq 1
      pos 4813
    doc 10
      freq 1
      pos 1666
  term difficulty
    doc 6
      freq 1
      pos 510
  term diffserv
    doc 0
      freq 2
      pos 403
      pos 1053
    doc 6
      freq 1
      pos 427
  term dig
    doc 14
      freq 1
      pos 2121
  term digest
    doc 10
      freq 24
      pos 274
      pos 529
      pos 567
      pos 886
      pos 1859
      pos 2596
      pos 2650
      pos 2667
      pos 4210
      pos 4232
      pos 4808
      pos 4811
      pos 4854
      pos 4879
      pos 5049
      pos 5312
      pos 5324
      pos 5407
      pos 6762
      pos 8211
      pos 9430
      pos 10083
      pos 10304
      pos 11883
    doc 16
      freq 3
      pos 2298
      pos 2380
      pos 2391
  term digit
    doc 10
      freq 5
      pos 4976
      pos 4978
      pos 5012
      pos 5041
      pos 5332
    doc 14
      freq 3
      pos 2082
      pos 2282
      pos 2938
  term digital
    doc 1
      freq 4
      pos 570
      pos 598
      pos 661
      pos 9144
    doc 2
      freq 3
      pos 3614
      pos 3635
      pos 3659
    doc 13
      freq 5
      pos 532
      pos 914
      pos 928
      pos 2959
      pos 6804
    doc 18
      freq 1
      pos 1689
  term digitally
    doc 5
      freq 1
      pos 232
  term digits
    doc 11
      freq 2
      pos 1026
      pos 5007
  term dimension
    doc 6
      freq 1
      pos 397
  term dimitr
    doc 0
      freq 1
      pos 15937
    doc 1
      freq 1
      pos 9185
    doc 4
      freq 1
      pos 5486
  term direct
    doc 0
      freq 2
      pos 11655
      pos 16009
    doc 10
      freq 5
      pos 10030
      pos 10232
      pos 10272
      pos 10290
      pos 10609
  term directed
    doc 0
      freq 1
      pos 16043
  term direction
    doc 0
      freq 14
      pos 8294
      pos 8323
      pos 8438
      pos 8459
      pos 8506
      pos 8527
      pos 8564
      pos 8584
      pos 8622
      pos 8654
      pos 8679
      pos 8699
      pos 8724
      pos 8744
    doc 1
      freq 5
      pos 3374
      pos 3385
      pos 3402
      pos 4723
      pos 4736
    doc 2
      freq 1
      pos 5988
    doc 5
      freq 1
      pos 2479
    doc 6
      freq 1
      pos 664
    doc 10
      freq 6
      pos 3493
      pos 3559
      pos 3582
      pos 3604
      pos 3691
      pos 4610
  term directional
    doc 1
      freq 2
      pos 1666
      pos 1674
    doc 13
      freq 4
      pos 1679
      pos 1711
      pos 1850
      pos 2275
  term directions
    doc 1
      freq 3
      pos 1695
      pos 1709
      pos 6202
    doc 3
      freq 1
      pos 5079
  term directives
    doc 8
      freq 2
      pos 123
      pos 379
  term directly
    doc 1
      freq 1
      pos 8101
    doc 2
      freq 1
      pos 3830
    doc 5
      freq 1
      pos 1191
    doc 6
      freq 1
      pos 2777
    doc 10
      freq 1
      pos 8922
    doc 11
      freq 1
      pos 902
    doc 12
      freq 1
      pos 1926
    doc 17
      freq 1
      pos 1199
    skipList 
      level 0
        skipDoc 17
        skipDocFP 757946
        impacts 
          impact 
            freq 1
            norm 98
        impactsEnd 
  term director
    doc 2
      freq 2
      pos 1287
      pos 5884
    doc 4
      freq 1
      pos 4855
  term directorat
    doc 2
      freq 1
      pos 1675
  term directors
    doc 2
      freq 2
      pos 412
      pos 415
    doc 7
      freq 1
      pos 295
  term directory
    doc 7
      freq 2
      pos 714
      pos 2038
    doc 13
      freq 4
      pos 453
      pos 2816
      pos 6788
      pos 6795
    doc 17
      freq 1
      pos 2136
  term dirk
    doc 13
      freq 1
      pos 6967
  term disabl
    doc 12
      freq 1
      pos 3714
  term disabled
    doc 0
      freq 1
      pos 12769
    doc 3
      freq 2
      pos 1802
      pos 1880
    doc 4
      freq 2
      pos 2703
      pos 5976
    doc 12
      freq 1
      pos 1830
  term disabling
    doc 0
      freq 2
      pos 1592
      pos 16051
  term disadvantag
    doc 5
      freq 2
      pos 2236
      pos 2460
    doc 12
      freq 1
      pos 2387
  term disallow
    doc 12
      freq 1
      pos 9397
  term disapprov
    doc 8
      freq 1
      pos 449
  term disc
    doc 4
      freq 3
      pos 376
      pos 1659
      pos 5193
  term discard
    doc 3
      freq 2
      pos 5348
      pos 5366
    doc 4
      freq 2
      pos 3139
      pos 3406
    doc 11
      freq 2
      pos 5015
      pos 8416
    doc 12
      freq 5
      pos 2974
      pos 8327
      pos 8576
      pos 8883
      pos 8997
    doc 15
      freq 2
      pos 1461
      pos 2971
  term discarded
    doc 3
      freq 1
      pos 3119
    doc 4
      freq 1
      pos 1430
    doc 11
      freq 2
      pos 4561
      pos 8291
    doc 12
      freq 1
      pos 9121
  term discarding
    doc 11
      freq 1
      pos 910
    doc 12
      freq 1
      pos 3029
    doc 13
      freq 1
      pos 6481
  term discerning
    doc 10
      freq 1
      pos 9679
  term disclaim
    doc 0
      freq 1
      pos 17295
    doc 1
      freq 1
      pos 9676
    doc 2
      freq 1
      pos 6473
    doc 3
      freq 1
      pos 6025
    doc 4
      freq 1
      pos 6180
    doc 5
      freq 1
      pos 4510
    doc 6
      freq 1
      pos 3310
    doc 7
      freq 1
      pos 3015
    doc 8
      freq 1
      pos 2232
    doc 9
      freq 1
      pos 1877
    doc 10
      freq 1
      pos 13538
    doc 11
      freq 1
      pos 10699
    doc 12
      freq 1
      pos 9549
    doc 13
      freq 1
      pos 7164
    doc 14
      freq 1
      pos 5630
    doc 15
      freq 1
      pos 4149
    doc 16
      freq 1
      pos 2760
    doc 17
      freq 1
      pos 2484
    doc 18
      freq 1
      pos 2272
    skipList 
      level 0
        skipDoc 7
        skipDocFP 760273
        impacts 
          impact 
            freq 1
            norm 100
        impactsEnd 
        skipDoc 15
        skipDocFP 760578
        impacts 
          impact 
            freq 1
            norm 95
        impactsEnd 
  term disclosed
    doc 2
      freq 1
      pos 5123
    doc 5
      freq 2
      pos 1290
      pos 2187
    doc 18
      freq 1
      pos 474
  term disclosing
    doc 14
      freq 1
      pos 109
  term disclosur
    doc 5
      freq 4
      pos 1407
      pos 1958
      pos 2033
      pos 3321
    doc 18
      freq 2
      pos 131
      pos 1684
  term disclosures
    doc 0
      freq 1
      pos 17425
    doc 1
      freq 1
      pos 9806
    doc 2
      freq 1
      pos 6603
    doc 3
      freq 1
      pos 6155
    doc 4
      freq 1
      pos 6310
    doc 5
      freq 1
      pos 4640
    doc 6
      freq 1
      pos 3440
    doc 7
      freq 1
      pos 3145
    doc 8
      freq 1
      pos 2362
    doc 9
      freq 1
      pos 2007
    doc 10
      freq 1
      pos 13668
    doc 11
      freq 1
      pos 10829
    doc 12
      freq 1
      pos 9679
    doc 13
      freq 1
      pos 7294
    doc 14
      freq 1
      pos 5760
    doc 15
      freq 1
      pos 4279
    doc 16
      freq 1
      pos 2890
    doc 17
      freq 1
      pos 2614
    doc 18
      freq 1
      pos 2402
    skipList 
      level 0
        skipDoc 7
        skipDocFP 761685
        impacts 
          impact 
            freq 1
            norm 100
        impactsEnd 
        skipDoc 15
        skipDocFP 761990
        impacts 
          impact 
            freq 1
            norm 95
        impactsEnd 
  term disconnected
    doc 12
      freq 1
      pos 5687
  term discover
    doc 10
      freq 1
      pos 4019
    doc 12
      freq 2
      pos 3976
      pos 5791
    doc 13
      freq 1
      pos 3180
  term discovered
    doc 1
      freq 2
      pos 2970
      pos 8529
    doc 2
      freq 2
      pos 4545
      pos 5040
    doc 10
      freq 1
      pos 6770
  term discovery
    doc 1
      freq 3
      pos 2077
      pos 8534
      pos 8544
    doc 2
      freq 1
      pos 4859
    doc 4
      freq 6
      pos 351
      pos 373
      pos 1689
      pos 2901
      pos 5202
      pos 5356
    doc 7
      freq 1
      pos 2003
    doc 10
      freq 1
      pos 13353
    doc 12
      freq 3
      pos 4084
      pos 4133
      pos 7777
    doc 13
      freq 1
      pos 2814
  term discrepancy
    doc 10
      freq 1
      pos 3171
  term discretion
    doc 6
      freq 1
      pos 153
  term discuss
    doc 0
      freq 1
      pos 16197
    doc 7
      freq 2
      pos 455
      pos 517
    doc 15
      freq 1
      pos 1764
  term discussed
    doc 1
      freq 6
      pos 984
      pos 990
      pos 3065
      pos 3360
      pos 7733
      pos 8815
    doc 2
      freq 1
      pos 388
    doc 3
      freq 3
      pos 4081
      pos 4162
      pos 5849
    doc 10
      freq 1
      pos 12208
    doc 11
      freq 1
      pos 9757
    doc 12
      freq 6
      pos 1287
      pos 5251
      pos 5804
      pos 8070
      pos 8622
      pos 9079
    doc 15
      freq 1
      pos 1012
    doc 16
      freq 1
      pos 1628
    doc 18
      freq 1
      pos 455
    skipList 
      level 0
        skipDoc 16
        skipDocFP 763787
        impacts 
          impact 
            freq 1
            norm 99
          impact 
            freq 3
            norm 107
          impact 
            freq 6
            norm 113
        impactsEnd 
  term discusses
    doc 3
      freq 1
      pos 494
    doc 12
      freq 1
      pos 744
    doc 13
      freq 2
      pos 1078
      pos 1555
    doc 15
      freq 1
      pos 448
  term discussion
    doc 0
      freq 2
      pos 46
      pos 15994
    doc 1
      freq 1
      pos 63
    doc 2
      freq 2
      pos 1342
      pos 5128
    doc 3
      freq 1
      pos 57
    doc 4
      freq 3
      pos 59
      pos 4109
      pos 4122
    doc 5
      freq 1
      pos 43
    doc 7
      freq 5
      pos 134
      pos 360
      pos 614
      pos 1173
      pos 1404
    doc 8
      freq 1
      pos 47
    doc 9
      freq 3
      pos 45
      pos 527
      pos 1630
    doc 10
      freq 1
      pos 48
    doc 12
      freq 5
      pos 487
      pos 2822
      pos 2886
      pos 4895
      pos 9056
    doc 14
      freq 1
      pos 47
    doc 15
      freq 3
      pos 1585
      pos 3542
      pos 3771
    doc 16
      freq 1
      pos 44
    doc 17
      freq 1
      pos 41
    doc 18
      freq 3
      pos 50
      pos 369
      pos 496
    skipList 
      level 0
        skipDoc 8
        skipDocFP 764796
        impacts 
          impact 
            freq 1
            norm 97
          impact 
            freq 5
            norm 100
        impactsEnd 
        skipDoc 18
        skipDocFP 765206
        impacts 
          impact 
            freq 3
            norm 95
          impact 
            freq 5
            norm 113
        impactsEnd 
  term discussions
    doc 2
      freq 2
      pos 1156
      pos 5966
    doc 5
      freq 1
      pos 4078
    doc 7
      freq 1
      pos 1799
  term display
    doc 0
      freq 7
      pos 1604
      pos 1703
      pos 1748
      pos 1799
      pos 1996
      pos 2023
      pos 2058
    doc 6
      freq 3
      pos 403
      pos 1360
      pos 2652
    doc 7
      freq 1
      pos 1954
    doc 10
      freq 24
      pos 279
      pos 3039
      pos 3057
      pos 3069
      pos 3080
      pos 3109
      pos 3113
      pos 3128
      pos 9557
      pos 9573
      pos 9615
      pos 9633
      pos 9645
      pos 9682
      pos 9703
      pos 9729
      pos 9759
      pos 9764
      pos 9806
      pos 9838
      pos 9858
      pos 9904
      pos 9913
      pos 9975
    doc 11
      freq 12
      pos 179
      pos 287
      pos 356
      pos 1140
      pos 2458
      pos 2612
      pos 2637
      pos 2742
      pos 5081
      pos 5093
      pos 6493
      pos 6502
    doc 17
      freq 3
      pos 1066
      pos 1081
      pos 1173
  term displayed
    doc 6
      freq 5
      pos 1259
      pos 1401
      pos 1532
      pos 1916
      pos 1957
    doc 10
      freq 1
      pos 636
    doc 17
      freq 2
      pos 1249
      pos 1256
  term displays
    doc 10
      freq 1
      pos 751
  term disposition
    doc 1
      freq 9
      pos 1546
      pos 7527
      pos 7550
      pos 7587
      pos 7611
      pos 7623
      pos 7667
      pos 7695
      pos 7706
  term disregards
    doc 12
      freq 1
      pos 6598
  term disrupt
    doc 0
      freq 1
      pos 16258
    doc 5
      freq 1
      pos 3330
    doc 13
      freq 1
      pos 6403
  term disseminated
    doc 13
      freq 2
      pos 443
      pos 6494
  term dissimilar
    doc 13
      freq 1
      pos 5566
  term distanc
    doc 13
      freq 3
      pos 218
      pos 3193
      pos 3232
  term distinct
    doc 5
      freq 1
      pos 1653
    doc 9
      freq 1
      pos 1308
    doc 11
      freq 1
      pos 2351
  term distinguish
    doc 3
      freq 3
      pos 2346
      pos 2383
      pos 2406
    doc 10
      freq 2
      pos 9336
      pos 11101
    doc 15
      freq 1
      pos 3143
  term distinguisher
    doc 8
      freq 1
      pos 1506
  term distribut
    doc 5
      freq 2
      pos 680
      pos 738
    doc 13
      freq 2
      pos 1641
      pos 3395
    doc 15
      freq 1
      pos 3459
  term distributed
    doc 1
      freq 2
      pos 2057
      pos 8164
    doc 5
      freq 2
      pos 2888
      pos 4277
    doc 7
      freq 2
      pos 707
      pos 2031
    doc 13
      freq 1
      pos 2198
  term distributes
    doc 10
      freq 1
      pos 10578
    doc 13
      freq 2
      pos 1763
      pos 4515
  term distributing
    doc 1
      freq 2
      pos 1777
      pos 1813
    doc 10
      freq 1
      pos 9908
    doc 13
      freq 4
      pos 662
      pos 707
      pos 2399
      pos 6368
  term distribution
    doc 0
      freq 1
      pos 74
    doc 1
      freq 6
      pos 42
      pos 91
      pos 180
      pos 736
      pos 1802
      pos 7922
    doc 2
      freq 2
      pos 44
      pos 2416
    doc 3
      freq 3
      pos 85
      pos 1559
      pos 4377
    doc 4
      freq 1
      pos 87
    doc 5
      freq 6
      pos 71
      pos 580
      pos 754
      pos 810
      pos 2871
      pos 4385
    doc 6
      freq 1
      pos 47
    doc 7
      freq 1
      pos 58
    doc 8
      freq 2
      pos 52
      pos 1805
    doc 9
      freq 1
      pos 73
    doc 10
      freq 1
      pos 76
    doc 11
      freq 1
      pos 60
    doc 12
      freq 1
      pos 50
    doc 13
      freq 5
      pos 59
      pos 227
      pos 731
      pos 3312
      pos 4177
    doc 14
      freq 1
      pos 54
    doc 15
      freq 1
      pos 58
    doc 16
      freq 1
      pos 72
    doc 17
      freq 1
      pos 69
    doc 18
      freq 1
      pos 78
    skipList 
      level 0
        skipDoc 7
        skipDocFP 769035
        impacts 
          impact 
            freq 1
            norm 100
          impact 
            freq 6
            norm 104
        impactsEnd 
        skipDoc 15
        skipDocFP 769511
        impacts 
          impact 
            freq 1
            norm 95
          impact 
            freq 2
            norm 97
          impact 
            freq 5
            norm 109
        impactsEnd 
  term disturbanc
    doc 12
      freq 1
      pos 2356
  term disused
    doc 12
      freq 3
      pos 6035
      pos 6091
      pos 6118
  term ditech
    doc 11
      freq 2
      pos 16
      pos 10537
  term ditechcom.com
    doc 11
      freq 1
      pos 10553
  term division
    doc 1
      freq 3
      pos 151
      pos 567
      pos 658
  term dj0234sxdfl3
    doc 11
      freq 2
      pos 6782
      pos 6874
  term djf77byoywlcr
    doc 10
      freq 1
      pos 12744
  term djybdjmyyv
    doc 11
      freq 1
      pos 9986
  term dkc
    doc 11
      freq 1
      pos 10486
  term dkfvgjkrtmwaerkkp
    doc 11
      freq 1
      pos 8744
  term dkn4i9kxjuzdvi5pj3sf1e6auhh37x8rjcbcjq7cyv2hzqu
    doc 11
      freq 1
      pos 10413
  term dlci
    doc 1
      freq 1
      pos 1633
    doc 8
      freq 3
      pos 633
      pos 789
      pos 1069
  term dna
    doc 15
      freq 1
      pos 3781
  term dname
    doc 12
      freq 2
      pos 826
      pos 854
  term dnolqau3v7
    doc 11
      freq 1
      pos 10467
  term dnpi6noizhbvqli1ysf
    doc 11
      freq 1
      pos 9900
  term dnrc.example.com
    doc 11
      freq 2
      pos 1452
      pos 1459
  term dns
    doc 7
      freq 2
      pos 2867
      pos 2878
    doc 10
      freq 2
      pos 10711
      pos 10719
    doc 12
      freq 235
      pos 27
      pos 77
      pos 88
      pos 98
      pos 105
      pos 111
      pos 135
      pos 144
      pos 156
      pos 162
      pos 165
      pos 185
      pos 212
      pos 219
      pos 228
      pos 242
      pos 251
      pos 315
      pos 321
      pos 327
      pos 340
      pos 355
      pos 362
      pos 367
      pos 373
      pos 380
      pos 386
      pos 410
      pos 417
      pos 427
      pos 454
      pos 504
      pos 518
      pos 537
      pos 545
      pos 562
      pos 579
      pos 597
      pos 644
      pos 650
      pos 665
      pos 677
      pos 706
      pos 719
      pos 752
      pos 791
      pos 868
      pos 874
      pos 877
      pos 879
      pos 911
      pos 935
      pos 1091
      pos 1102
      pos 1129
      pos 1134
      pos 1226
      pos 1230
      pos 1303
      pos 1345
      pos 1423
      pos 1563
      pos 1576
      pos 1617
      pos 1625
      pos 1668
      pos 1681
      pos 1700
      pos 1753
      pos 1905
      pos 1916
      pos 1948
      pos 1957
      pos 1964
      pos 2008
      pos 2013
      pos 2233
      pos 2282
      pos 2427
      pos 2536
      pos 2641
      pos 2653
      pos 2804
      pos 3025
      pos 3164
      pos 3183
      pos 3220
      pos 3248
      pos 3389
      pos 3459
      pos 3495
      pos 3673
      pos 3701
      pos 3818
      pos 3832
      pos 3877
      pos 3964
      pos 3980
      pos 3986
      pos 4020
      pos 4082
      pos 4103
      pos 4131
      pos 4166
      pos 4187
      pos 4200
      pos 4207
      pos 4219
      pos 4251
      pos 4262
      pos 4274
      pos 4287
      pos 4309
      pos 4318
      pos 4375
      pos 4378
      pos 4409
      pos 4411
      pos 4424
      pos 4495
      pos 4527
      pos 4565
      pos 4582
      pos 4623
      pos 4642
      pos 4814
      pos 4852
      pos 4878
      pos 4903
      pos 4922
      pos 4927
      pos 4950
      pos 4959
      pos 4965
      pos 5016
      pos 5056
      pos 5124
      pos 5168
      pos 5189
      pos 5262
      pos 5265
      pos 5292
      pos 5365
      pos 5395
      pos 5405
      pos 5425
      pos 5436
      pos 5443
      pos 5473
      pos 5502
      pos 5576
      pos 5591
      pos 5602
      pos 5653
      pos 5693
      pos 5793
      pos 5817
      pos 5861
      pos 5941
      pos 5957
      pos 5965
      pos 6022
      pos 6082
      pos 6107
      pos 6127
      pos 6196
      pos 6226
      pos 6251
      pos 6266
      pos 6291
      pos 6304
      pos 6310
      pos 6371
      pos 6386
      pos 6493
      pos 6501
      pos 6522
      pos 6525
      pos 6574
      pos 6596
      pos 6609
      pos 6644
      pos 6844
      pos 6864
      pos 6923
      pos 6950
      pos 6989
      pos 7028
      pos 7043
      pos 7064
      pos 7092
      pos 7116
      pos 7220
      pos 7236
      pos 7247
      pos 7269
      pos 7283
      pos 7334
      pos 7377
      pos 7446
      pos 7465
      pos 7497
      pos 7505
      pos 7521
      pos 7566
      pos 7709
      pos 7718
      pos 7735
      pos 7750
      pos 7763
      pos 7829
      pos 7850
      pos 7889
      pos 7899
      pos 7918
      pos 7936
      pos 7944
      pos 7964
      pos 8002
      pos 8006
      pos 8018
      pos 8023
      pos 8083
      pos 8242
      pos 8639
      pos 8722
      pos 8763
      pos 9051
      pos 9174
      pos 9326
      pos 9344
      pos 9368
      pos 9390
      pos 9423
      pos 9474
    doc 14
      freq 90
      pos 18
      pos 84
      pos 138
      pos 145
      pos 156
      pos 163
      pos 198
      pos 217
      pos 339
      pos 384
      pos 451
      pos 457
      pos 530
      pos 560
      pos 586
      pos 665
      pos 689
      pos 844
      pos 904
      pos 923
      pos 958
      pos 1099
      pos 1150
      pos 1156
      pos 1221
      pos 1355
      pos 1368
      pos 1377
      pos 1383
      pos 1550
      pos 1560
      pos 1786
      pos 1871
      pos 1914
      pos 2053
      pos 2102
      pos 2136
      pos 2150
      pos 2161
      pos 2177
      pos 2237
      pos 2261
      pos 2291
      pos 2308
      pos 2338
      pos 2352
      pos 2405
      pos 2418
      pos 2493
      pos 2552
      pos 2660
      pos 2906
      pos 3236
      pos 3259
      pos 3543
      pos 3552
      pos 3841
      pos 3850
      pos 3865
      pos 4137
      pos 4162
      pos 4171
      pos 4223
      pos 4232
      pos 4237
      pos 4288
      pos 4297
      pos 4302
      pos 4410
      pos 4419
      pos 4424
      pos 4504
      pos 4513
      pos 4518
      pos 4586
      pos 4595
      pos 4964
      pos 4973
      pos 4979
      pos 5028
      pos 5043
      pos 5146
      pos 5152
      pos 5192
      pos 5399
      pos 5414
      pos 5422
      pos 5444
      pos 5458
      pos 5551
    doc 15
      freq 23
      pos 230
      pos 235
      pos 417
      pos 642
      pos 648
      pos 677
      pos 1051
      pos 1065
      pos 1100
      pos 1282
      pos 1293
      pos 1337
      pos 1342
      pos 1406
      pos 1944
      pos 1975
      pos 2002
      pos 2012
      pos 2081
      pos 2817
      pos 2961
      pos 3079
      pos 3111
    doc 18
      freq 4
      pos 1216
      pos 2071
      pos 2096
      pos 2119
  term dnsext
    doc 12
      freq 1
      pos 7639
    doc 18
      freq 1
      pos 516
  term dnskey
    doc 18
      freq 3
      pos 1164
      pos 1168
      pos 1200
  term dnssec
    doc 14
      freq 7
      pos 115
      pos 298
      pos 311
      pos 2649
      pos 5479
      pos 5487
      pos 5497
    doc 18
      freq 7
      pos 28
      pos 99
      pos 186
      pos 431
      pos 712
      pos 1756
      pos 1961
  term do
    doc 0
      freq 15
      pos 1858
      pos 3438
      pos 4084
      pos 4501
      pos 5153
      pos 5182
      pos 5208
      pos 5210
      pos 6553
      pos 8873
      pos 9475
      pos 9658
      pos 9884
      pos 13806
      pos 16648
    doc 1
      freq 8
      pos 1317
      pos 1344
      pos 1449
      pos 1804
      pos 6942
      pos 8289
      pos 8331
      pos 8368
    doc 2
      freq 1
      pos 5931
    doc 3
      freq 3
      pos 2916
      pos 3439
      pos 3534
    doc 4
      freq 1
      pos 2329
    doc 5
      freq 1
      pos 3012
    doc 6
      freq 2
      pos 2140
      pos 2775
    doc 7
      freq 5
      pos 1473
      pos 1515
      pos 1565
      pos 1705
      pos 1724
    doc 9
      freq 1
      pos 1363
    doc 10
      freq 3
      pos 1646
      pos 2549
      pos 2812
    doc 11
      freq 3
      pos 1813
      pos 4421
      pos 6067
    doc 12
      freq 10
      pos 1181
      pos 1441
      pos 1922
      pos 1980
      pos 2230
      pos 3527
      pos 3866
      pos 8085
      pos 8313
      pos 8676
    doc 13
      freq 1
      pos 3935
    doc 14
      freq 2
      pos 336
      pos 2571
    doc 15
      freq 6
      pos 774
      pos 2419
      pos 2431
      pos 2750
      pos 3075
      pos 3268
    doc 16
      freq 1
      pos 361
    doc 18
      freq 1
      pos 1561
    skipList 
      level 0
        skipDoc 7
        skipDocFP 777512
        impacts 
          impact 
            freq 5
            norm 100
          impact 
            freq 8
            norm 113
          impact 
            freq 15
            norm 120
        impactsEnd 
        skipDoc 16
        skipDocFP 778239
        impacts 
          impact 
            freq 1
            norm 95
          impact 
            freq 6
            norm 104
          impact 
            freq 10
            norm 113
        impactsEnd 
  term docs
    doc 2
      freq 2
      pos 2767
      pos 2790
  term doctor
    doc 2
      freq 2
      pos 1272
      pos 1331
  term doctors
    doc 2
      freq 4
      pos 1261
      pos 1663
      pos 1683
      pos 1687
  term document
    doc 0
      freq 12
      pos 33
      pos 112
      pos 302
      pos 975
      pos 1123
      pos 1157
      pos 1164
      pos 15814
      pos 15847
      pos 17233
      pos 17259
      pos 17369
    doc 1
      freq 28
      pos 50
      pos 166
      pos 727
      pos 959
      pos 961
      pos 993
      pos 1117
      pos 1177
      pos 1770
      pos 1806
      pos 1829
      pos 1899
      pos 1973
      pos 2049
      pos 2270
      pos 2277
      pos 3703
      pos 3747
      pos 5124
      pos 5571
      pos 7254
      pos 7748
      pos 7798
      pos 7902
      pos 7931
      pos 9614
      pos 9640
      pos 9750
    doc 2
      freq 18
      pos 87
      pos 147
      pos 304
      pos 816
      pos 1722
      pos 1736
      pos 1769
      pos 1932
      pos 3481
      pos 4091
      pos 4567
      pos 5237
      pos 5243
      pos 5942
      pos 5952
      pos 6411
      pos 6437
      pos 6547
    doc 3
      freq 22
      pos 44
      pos 132
      pos 384
      pos 416
      pos 434
      pos 493
      pos 720
      pos 773
      pos 830
      pos 1252
      pos 1500
      pos 1541
      pos 1712
      pos 1860
      pos 3140
      pos 4144
      pos 4173
      pos 5579
      pos 5866
      pos 5963
      pos 5989
      pos 6099
    doc 4
      freq 24
      pos 46
      pos 103
      pos 257
      pos 322
      pos 391
      pos 411
      pos 430
      pos 461
      pos 750
      pos 2051
      pos 4761
      pos 4983
      pos 5016
      pos 5038
      pos 5044
      pos 5054
      pos 5452
      pos 5518
      pos 5522
      pos 5898
      pos 5960
      pos 6118
      pos 6144
      pos 6254
    doc 5
      freq 24
      pos 30
      pos 194
      pos 570
      pos 749
      pos 876
      pos 944
      pos 975
      pos 1009
      pos 1065
      pos 1132
      pos 2678
      pos 2809
      pos 2831
      pos 2853
      pos 2886
      pos 3011
      pos 3025
      pos 3263
      pos 3428
      pos 3696
      pos 4099
      pos 4448
      pos 4474
      pos 4584
    doc 6
      freq 12
      pos 89
      pos 150
      pos 157
      pos 612
      pos 683
      pos 2774
      pos 2814
      pos 2821
      pos 3173
      pos 3243
      pos 3274
      pos 3384
    doc 7
      freq 12
      pos 236
      pos 350
      pos 370
      pos 471
      pos 1134
      pos 1163
      pos 1262
      pos 1661
      pos 1729
      pos 2953
      pos 2979
      pos 3089
    doc 8
      freq 19
      pos 34
      pos 68
      pos 104
      pos 220
      pos 325
      pos 382
      pos 510
      pos 612
      pos 841
      pos 990
      pos 1167
      pos 1284
      pos 1348
      pos 1479
      pos 1538
      pos 1680
      pos 2170
      pos 2196
      pos 2306
    doc 9
      freq 10
      pos 32
      pos 244
      pos 362
      pos 1057
      pos 1122
      pos 1531
      pos 1559
      pos 1815
      pos 1841
      pos 1951
    doc 10
      freq 46
      pos 35
      pos 122
      pos 405
      pos 432
      pos 650
      pos 673
      pos 860
      pos 939
      pos 1256
      pos 1331
      pos 1532
      pos 1576
      pos 1793
      pos 2099
      pos 3673
      pos 3795
      pos 3854
      pos 4504
      pos 4766
      pos 5450
      pos 5746
      pos 5771
      pos 7434
      pos 7775
      pos 8077
      pos 8215
      pos 8383
      pos 9055
      pos 9513
      pos 9784
      pos 9947
      pos 10895
      pos 11002
      pos 11446
      pos 11483
      pos 11556
      pos 11644
      pos 11738
      pos 11851
      pos 12149
      pos 12355
      pos 12432
      pos 12855
      pos 13476
      pos 13502
      pos 13612
    doc 11
      freq 24
      pos 77
      pos 102
      pos 561
      pos 574
      pos 665
      pos 715
      pos 769
      pos 772
      pos 807
      pos 852
      pos 2053
      pos 3765
      pos 9312
      pos 9363
      pos 9380
      pos 9429
      pos 9461
      pos 9513
      pos 9560
      pos 9772
      pos 9839
      pos 10637
      pos 10663
      pos 10773
    doc 12
      freq 8
      pos 550
      pos 841
      pos 3958
      pos 6517
      pos 6837
      pos 9487
      pos 9513
      pos 9623
    doc 13
      freq 12
      pos 147
      pos 1027
      pos 1029
      pos 1072
      pos 1110
      pos 1149
      pos 1201
      pos 3786
      pos 4952
      pos 7102
      pos 7128
      pos 7238
    doc 14
      freq 7
      pos 70
      pos 388
      pos 428
      pos 578
      pos 5568
      pos 5594
      pos 5704
    doc 15
      freq 15
      pos 129
      pos 164
      pos 447
      pos 501
      pos 529
      pos 1016
      pos 1664
      pos 1688
      pos 2329
      pos 3842
      pos 3865
      pos 3894
      pos 4087
      pos 4113
      pos 4223
    doc 16
      freq 8
      pos 31
      pos 416
      pos 850
      pos 1035
      pos 1667
      pos 2698
      pos 2724
      pos 2834
    doc 17
      freq 15
      pos 28
      pos 85
      pos 110
      pos 225
      pos 265
      pos 285
      pos 938
      pos 1265
      pos 1285
      pos 1294
      pos 1966
      pos 1991
      pos 2422
      pos 2448
      pos 2558
    doc 18
      freq 13
      pos 37
      pos 94
      pos 222
      pos 299
      pos 400
      pos 512
      pos 886
      pos 1241
      pos 2012
      pos 2055
      pos 2210
      pos 2236
      pos 2346
    skipList 
      level 0
        skipDoc 7
        skipDocFP 779656
        impacts 
          impact 
            freq 12
            norm 100
          impact 
            freq 24
            norm 104
          impact 
            freq 28
            norm 113
        impactsEnd 
        skipDoc 15
        skipDocFP 782078
        impacts 
          impact 
            freq 10
            norm 95
          impact 
            freq 19
            norm 97
          impact 
            freq 24
            norm 114
          impact 
            freq 46
            norm 116
        impactsEnd 
  term documentation
    doc 12
      freq 1
      pos 85
  term documented
    doc 2
      freq 2
      pos 3758
      pos 5893
    doc 7
      freq 2
      pos 87
      pos 1578
    doc 10
      freq 1
      pos 11332
    doc 12
      freq 1
      pos 1691
  term documents
    doc 0
      freq 2
      pos 204
      pos 17412
    doc 1
      freq 4
      pos 196
      pos 463
      pos 559
      pos 9793
    doc 2
      freq 11
      pos 963
      pos 1355
      pos 1989
      pos 2096
      pos 3362
      pos 5484
      pos 5520
      pos 5553
      pos 5559
      pos 5605
      pos 6590
    doc 3
      freq 1
      pos 6142
    doc 4
      freq 8
      pos 358
      pos 362
      pos 4907
      pos 4990
      pos 5002
      pos 5458
      pos 5951
      pos 6297
    doc 5
      freq 1
      pos 4627
    doc 6
      freq 1
      pos 3427
    doc 7
      freq 20
      pos 35
      pos 75
      pos 99
      pos 186
      pos 253
      pos 283
      pos 340
      pos 428
      pos 505
      pos 599
      pos 1184
      pos 1289
      pos 1394
      pos 1411
      pos 1665
      pos 1690
      pos 1692
      pos 1733
      pos 1744
      pos 3132
    doc 8
      freq 1
      pos 2349
    doc 9
      freq 1
      pos 1994
    doc 10
      freq 1
      pos 13655
    doc 11
      freq 1
      pos 10816
    doc 12
      freq 2
      pos 629
      pos 9666
    doc 13
      freq 1
      pos 7281
    doc 14
      freq 1
      pos 5747
    doc 15
      freq 1
      pos 4266
    doc 16
      freq 2
      pos 1637
      pos 2877
    doc 17
      freq 1
      pos 2601
    doc 18
      freq 1
      pos 2389
    skipList 
      level 0
        skipDoc 7
        skipDocFP 785826
        impacts 
          impact 
            freq 20
            norm 100
        impactsEnd 
        skipDoc 15
        skipDocFP 786713
        impacts 
          impact 
            freq 1
            norm 95
          impact 
            freq 2
            norm 113
        impactsEnd 
  term dod
    doc 17
      freq 6
      pos 531
      pos 868
      pos 893
      pos 2175
      pos 2215
      pos 2240
  term dodiis
    doc 7
      freq 1
      pos 1923
  term does
    doc 0
      freq 8
      pos 1464
      pos 11811
      pos 12557
      pos 13703
      pos 13996
      pos 14104
      pos 16702
      pos 17387
    doc 1
      freq 15
      pos 702
      pos 1771
      pos 2989
      pos 3704
      pos 3786
      pos 5323
      pos 5783
      pos 5795
      pos 6197
      pos 6444
      pos 7025
      pos 7052
      pos 8672
      pos 8715
      pos 9768
    doc 2
      freq 3
      pos 35
      pos 5734
      pos 6565
    doc 3
      freq 5
      pos 1199
      pos 2085
      pos 2571
      pos 5804
      pos 6117
    doc 4
      freq 6
      pos 336
      pos 1169
      pos 1570
      pos 1789
      pos 4256
      pos 6272
    doc 5
      freq 6
      pos 561
      pos 1183
      pos 2451
      pos 3099
      pos 3679
      pos 4602
    doc 6
      freq 2
      pos 38
      pos 3402
    doc 7
      freq 3
      pos 49
      pos 1446
      pos 3107
    doc 8
      freq 1
      pos 2324
    doc 9
      freq 4
      pos 846
      pos 1201
      pos 1449
      pos 1969
    doc 10
      freq 28
      pos 134
      pos 995
      pos 3035
      pos 3082
      pos 3441
      pos 3593
      pos 3685
      pos 4096
      pos 4226
      pos 4345
      pos 4723
      pos 5176
      pos 5241
      pos 5255
      pos 5852
      pos 6718
      pos 7065
      pos 8811
      pos 8898
      pos 9183
      pos 9369
      pos 9635
      pos 10052
      pos 10105
      pos 10907
      pos 11789
      pos 11878
      pos 13630
    doc 11
      freq 16
      pos 51
      pos 666
      pos 679
      pos 847
      pos 1400
      pos 1790
      pos 3741
      pos 4206
      pos 4986
      pos 6818
      pos 7429
      pos 7953
      pos 7980
      pos 8991
      pos 9381
      pos 10791
    doc 12
      freq 17
      pos 41
      pos 998
      pos 1037
      pos 1569
      pos 2461
      pos 2672
      pos 3289
      pos 3352
      pos 3608
      pos 4361
      pos 4627
      pos 4644
      pos 5631
      pos 5677
      pos 6847
      pos 8881
      pos 9641
    doc 13
      freq 7
      pos 50
      pos 1769
      pos 3769
      pos 4537
      pos 4788
      pos 4953
      pos 7256
    doc 14
      freq 6
      pos 38
      pos 389
      pos 1801
      pos 2316
      pos 2630
      pos 5722
    doc 15
      freq 7
      pos 49
      pos 1665
      pos 2696
      pos 2739
      pos 2845
      pos 3824
      pos 4241
    doc 16
      freq 6
      pos 345
      pos 802
      pos 819
      pos 1113
      pos 1603
      pos 2852
    doc 17
      freq 2
      pos 356
      pos 2576
    doc 18
      freq 4
      pos 530
      pos 1242
      pos 1589
      pos 2364
    skipList 
      level 0
        skipDoc 7
        skipDocFP 787720
        impacts 
          impact 
            freq 3
            norm 100
          impact 
            freq 6
            norm 104
          impact 
            freq 15
            norm 113
        impactsEnd 
        skipDoc 15
        skipDocFP 788623
        impacts 
          impact 
            freq 4
            norm 95
          impact 
            freq 7
            norm 104
          impact 
            freq 17
            norm 113
          impact 
            freq 28
            norm 116
        impactsEnd 
  term doesn't
    doc 10
      freq 1
      pos 2016
    doc 11
      freq 2
      pos 1926
      pos 7501
    doc 16
      freq 1
      pos 1362
  term doing
    doc 4
      freq 1
      pos 917
    doc 10
      freq 2
      pos 1479
      pos 9085
    doc 11
      freq 1
      pos 5443
    doc 12
      freq 2
      pos 2023
      pos 4257
    doc 15
      freq 1
      pos 2520
  term domain
    doc 0
      freq 9
      pos 566
      pos 595
      pos 1286
      pos 1311
      pos 1906
      pos 4042
      pos 4451
      pos 4688
      pos 5808
    doc 3
      freq 1
      pos 546
    doc 7
      freq 7
      pos 898
      pos 904
      pos 1419
      pos 2362
      pos 2368
      pos 2445
      pos 2462
    doc 9
      freq 1
      pos 408
    doc 10
      freq 84
      pos 294
      pos 989
      pos 1084
      pos 1177
      pos 1230
      pos 1276
      pos 1288
      pos 1301
      pos 1393
      pos 1849
      pos 1933
      pos 1963
      pos 2022
      pos 2041
      pos 2141
      pos 2163
      pos 2204
      pos 2405
      pos 2428
      pos 2707
      pos 2834
      pos 2840
      pos 2998
      pos 3632
      pos 3879
      pos 3936
      pos 3947
      pos 3977
      pos 4002
      pos 4042
      pos 4473
      pos 4570
      pos 4679
      pos 5422
      pos 5651
      pos 6016
      pos 6126
      pos 6139
      pos 7571
      pos 7582
      pos 7653
      pos 7736
      pos 7928
      pos 7938
      pos 7954
      pos 7963
      pos 9203
      pos 9816
      pos 9955
      pos 10070
      pos 10102
      pos 10118
      pos 10345
      pos 10364
      pos 10383
      pos 10398
      pos 10474
      pos 10534
      pos 10564
      pos 10570
      pos 10577
      pos 10596
      pos 10613
      pos 10618
      pos 10658
      pos 10666
      pos 10684
      pos 10729
      pos 10807
      pos 10828
      pos 10963
      pos 11027
      pos 11042
      pos 11047
      pos 11220
      pos 11247
      pos 11260
      pos 11271
      pos 12318
      pos 12327
      pos 12336
      pos 12944
      pos 13050
      pos 13074
    doc 12
      freq 11
      pos 74
      pos 2335
      pos 2399
      pos 5099
      pos 5620
      pos 6321
      pos 7000
      pos 7025
      pos 7113
      pos 7217
      pos 7244
    doc 14
      freq 4
      pos 445
      pos 2754
      pos 5365
      pos 5379
    doc 15
      freq 5
      pos 526
      pos 1162
      pos 1356
      pos 1399
      pos 2056
    doc 16
      freq 1
      pos 940
    skipList 
      level 0
        skipDoc 15
        skipDocFP 791336
        impacts 
          impact 
            freq 1
            norm 95
          impact 
            freq 7
            norm 100
          impact 
            freq 11
            norm 113
          impact 
            freq 84
            norm 116
        impactsEnd 
  term domain's
    doc 10
      freq 1
      pos 10693
  term domains
    doc 10
      freq 8
      pos 1441
      pos 7836
      pos 7900
      pos 9661
      pos 10456
      pos 11062
      pos 11088
      pos 11105
    doc 12
      freq 1
      pos 7150
  term dominant
    doc 2
      freq 1
      pos 3689
  term don
    doc 0
      freq 1
      pos 15929
  term don't
    doc 4
      freq 1
      pos 5635
    doc 12
      freq 1
      pos 604
    doc 15
      freq 1
      pos 2735
  term dondet
    doc 5
      freq 1
      pos 4091
  term done
    doc 1
      freq 2
      pos 1736
      pos 4742
    doc 3
      freq 2
      pos 1384
      pos 5183
    doc 4
      freq 1
      pos 859
    doc 12
      freq 7
      pos 1783
      pos 3472
      pos 4844
      pos 5505
      pos 6928
      pos 8740
      pos 8752
    doc 13
      freq 1
      pos 841
  term doolan
    doc 1
      freq 1
      pos 8914
    doc 3
      freq 1
      pos 4612
  term doqtrucpp4j0kx
    doc 11
      freq 1
      pos 10133
  term dormant
    doc 2
      freq 1
      pos 4288
  term dorothy
    doc 2
      freq 2
      pos 1771
      pos 6009
  term dos
    doc 13
      freq 7
      pos 328
      pos 6364
      pos 6407
      pos 6415
      pos 6423
      pos 6438
      pos 6446
  term dot
    doc 0
      freq 1
      pos 1119
  term doubl
    doc 10
      freq 1
      pos 2296
  term doug
    doc 11
      freq 1
      pos 9588
  term down
    doc 0
      freq 6
      pos 721
      pos 8969
      pos 9004
      pos 12644
      pos 16080
      pos 16265
    doc 1
      freq 3
      pos 4853
      pos 4907
      pos 5200
    doc 9
      freq 1
      pos 1568
    doc 10
      freq 2
      pos 9491
      pos 9530
    doc 15
      freq 1
      pos 1484
  term downgrad
    doc 10
      freq 1
      pos 8453
  term downgrading
    doc 5
      freq 4
      pos 310
      pos 3161
      pos 3176
      pos 3462
    doc 7
      freq 4
      pos 744
      pos 927
      pos 2088
      pos 2391
  term download
    doc 13
      freq 1
      pos 3355
    doc 16
      freq 3
      pos 151
      pos 349
      pos 1763
  term downloading
    doc 0
      freq 1
      pos 12000
    doc 10
      freq 1
      pos 3966
    doc 13
      freq 1
      pos 3224
  term downstream
    doc 1
      freq 2
      pos 1847
      pos 2061
    doc 6
      freq 2
      pos 1589
      pos 2419
  term dqjpc7mbg71axyl5rdcl9henu5wqc0jznvkbic313mnaf4
    doc 11
      freq 1
      pos 9924
  term dqos
    doc 6
      freq 1
      pos 2929
  term dr
    doc 1
      freq 2
      pos 9289
      pos 9344
    doc 3
      freq 2
      pos 4758
      pos 4847
    doc 6
      freq 1
      pos 3128
  term dr5amnn25xtflv
    doc 10
      freq 1
      pos 12808
  term dra
    doc 10
      freq 1
      pos 12469
  term draft
    doc 2
      freq 4
      pos 1428
      pos 1506
      pos 2565
      pos 4653
    doc 7
      freq 2
      pos 172
      pos 1633
    doc 11
      freq 1
      pos 748
    doc 16
      freq 6
      pos 1757
      pos 1777
      pos 1881
      pos 1903
      pos 1938
      pos 2158
  term drafts
    doc 2
      freq 4
      pos 4062
      pos 4765
      pos 4822
      pos 5516
    doc 16
      freq 12
      pos 1775
      pos 1781
      pos 1800
      pos 1809
      pos 1828
      pos 1936
      pos 2061
      pos 2070
      pos 2156
      pos 2162
      pos 2181
      pos 2190
  term drain
    doc 6
      freq 8
      pos 643
      pos 1188
      pos 1195
      pos 1223
      pos 1245
      pos 1346
      pos 1651
      pos 2192
  term draves
    doc 12
      freq 1
      pos 7128
  term drawbacks
    doc 15
      freq 1
      pos 1579
  term dreznwoe5l0y6peaqerdhgv5nx
    doc 10
      freq 1
      pos 12668
  term drift
    doc 5
      freq 4
      pos 1173
      pos 2175
      pos 2437
      pos 2542
  term drive
    doc 1
      freq 4
      pos 9193
      pos 9259
      pos 9275
      pos 9580
    doc 3
      freq 3
      pos 4789
      pos 4965
      pos 4979
    doc 4
      freq 2
      pos 6050
      pos 6066
    doc 9
      freq 1
      pos 1772
    doc 10
      freq 1
      pos 13436
    doc 16
      freq 1
      pos 2657
    doc 18
      freq 1
      pos 2166
  term driven
    doc 13
      freq 6
      pos 282
      pos 4271
      pos 4284
      pos 4286
      pos 4308
      pos 4324
  term droms
    doc 12
      freq 5
      pos 6803
      pos 7172
      pos 7281
      pos 7299
      pos 7393
    doc 15
      freq 5
      pos 3850
      pos 3899
      pos 3924
      pos 3938
      pos 3963
  term drop
    doc 0
      freq 6
      pos 16216
      pos 16219
      pos 16222
      pos 16245
      pos 16274
      pos 16328
    doc 3
      freq 5
      pos 322
      pos 1630
      pos 5799
      pos 5807
      pos 5830
    doc 11
      freq 2
      pos 6958
      pos 8447
    doc 12
      freq 1
      pos 1696
    doc 13
      freq 1
      pos 4580
  term dropped
    doc 0
      freq 14
      pos 7340
      pos 7488
      pos 12862
      pos 12907
      pos 13161
      pos 13263
      pos 13480
      pos 13578
      pos 13670
      pos 13772
      pos 13845
      pos 13917
      pos 14057
      pos 14186
    doc 3
      freq 5
      pos 2906
      pos 2994
      pos 3031
      pos 3075
      pos 4289
    doc 4
      freq 2
      pos 1545
      pos 2275
  term ds
    doc 18
      freq 1
      pos 1138
  term ds1
    doc 8
      freq 1
      pos 746
  term ds3
    doc 8
      freq 1
      pos 761
  term dse3ve0nc8x9nmvljw7gsmgfcncuo4odtf
    doc 10
      freq 1
      pos 6282
  term dsp
    doc 0
      freq 2
      pos 10404
      pos 10772
  term dtnyuk7drlq
    doc 11
      freq 1
      pos 9943
  term dtr9
    doc 11
      freq 1
      pos 10081
  term dttaytv5dtejxyy7ffk0ps58ukihyh8e7d3ylsa7zckxqrmtvojvmmgz1a1m
    doc 11
      freq 1
      pos 10056
  term dual
    doc 0
      freq 1
      pos 16974
    doc 7
      freq 1
      pos 1981
    doc 12
      freq 6
      pos 2661
      pos 4094
      pos 4098
      pos 4156
      pos 4184
      pos 7799
    doc 15
      freq 38
      pos 33
      pos 134
      pos 195
      pos 211
      pos 306
      pos 425
      pos 456
      pos 516
      pos 595
      pos 636
      pos 770
      pos 814
      pos 831
      pos 1026
      pos 1076
      pos 1379
      pos 1394
      pos 1430
      pos 1595
      pos 1754
      pos 2149
      pos 2272
      pos 2359
      pos 2422
      pos 2438
      pos 2595
      pos 2677
      pos 3007
      pos 3244
      pos 3289
      pos 3329
      pos 3343
      pos 3408
      pos 3564
      pos 3758
      pos 3803
      pos 4009
      pos 4072
  term due
    doc 1
      freq 1
      pos 4686
    doc 2
      freq 4
      pos 642
      pos 2161
      pos 5311
      pos 5614
    doc 4
      freq 4
      pos 1578
      pos 1615
      pos 2276
      pos 2616
    doc 5
      freq 1
      pos 3684
    doc 6
      freq 6
      pos 479
      pos 928
      pos 1638
      pos 2399
      pos 2434
      pos 2520
    doc 9
      freq 4
      pos 307
      pos 636
      pos 659
      pos 1624
    doc 11
      freq 3
      pos 796
      pos 4803
      pos 6650
    doc 12
      freq 4
      pos 1831
      pos 4240
      pos 5919
      pos 8103
    doc 13
      freq 1
      pos 3780
    skipList 
      level 0
        skipDoc 12
        skipDocFP 800366
        impacts 
          impact 
            freq 4
            norm 95
          impact 
            freq 6
            norm 101
        impactsEnd 
  term duid
    doc 15
      freq 3
      pos 3158
      pos 3160
      pos 3211
  term duids
    doc 15
      freq 4
      pos 2556
      pos 2572
      pos 2607
      pos 2640
  term duling
    doc 6
      freq 1
      pos 3161
  term dummy
    doc 3
      freq 1
      pos 2587
  term duna1r98rxdpw1sm6tvlftxdsqmls7
    doc 11
      freq 1
      pos 10228
  term duplicat
    doc 3
      freq 2
      pos 1627
      pos 1646
    doc 12
      freq 1
      pos 3580
  term duplication
    doc 8
      freq 1
      pos 404
    doc 10
      freq 1
      pos 8620
    doc 15
      freq 1
      pos 2723
  term durand
    doc 12
      freq 35
      pos 4
      pos 231
      pos 493
      pos 857
      pos 1215
      pos 1552
      pos 1937
      pos 2271
      pos 2642
      pos 3014
      pos 3378
      pos 3807
      pos 4189
      pos 4554
      pos 5005
      pos 5414
      pos 5850
      pos 6240
      pos 6633
      pos 6978
      pos 7199
      pos 7225
      pos 7329
      pos 7454
      pos 7678
      pos 7698
      pos 7792
      pos 7878
      pos 8231
      pos 8628
      pos 9040
      pos 9412
      pos 9429
      pos 9463
      pos 9796
  term duration
    doc 5
      freq 6
      pos 1393
      pos 1451
      pos 1951
      pos 2030
      pos 2440
      pos 3326
    doc 10
      freq 2
      pos 5708
      pos 8551
    doc 13
      freq 1
      pos 3811
  term during
    doc 0
      freq 2
      pos 6644
      pos 9165
    doc 1
      freq 1
      pos 2834
    doc 2
      freq 5
      pos 4317
      pos 4920
      pos 5030
      pos 5452
      pos 5858
    doc 6
      freq 7
      pos 1096
      pos 1715
      pos 1844
      pos 1870
      pos 1941
      pos 1948
      pos 2017
    doc 7
      freq 1
      pos 630
    doc 10
      freq 1
      pos 3560
    doc 11
      freq 2
      pos 8706
      pos 9551
    doc 12
      freq 2
      pos 6819
      pos 6829
    doc 13
      freq 3
      pos 2456
      pos 3126
      pos 4996
    doc 14
      freq 3
      pos 295
      pos 2399
      pos 2477
    doc 17
      freq 1
      pos 1606
    skipList 
      level 0
        skipDoc 12
        skipDocFP 802608
        impacts 
          impact 
            freq 1
            norm 100
          impact 
            freq 7
            norm 101
        impactsEnd 
  term duties
    doc 17
      freq 1
      pos 1487
  term duty
    doc 2
      freq 1
      pos 5361
  term dv59xa1v
    doc 11
      freq 1
      pos 10288
  term dvb
    doc 13
      freq 1
      pos 531
  term dvn
    doc 11
      freq 1
      pos 10501
  term dvrs
    doc 13
      freq 1
      pos 931
  term dvvsbxg4svxow11wtk3oroiza1
    doc 11
      freq 1
      pos 9950
  term dx5skvsu
    doc 11
      freq 1
      pos 10357
  term dxc
    doc 11
      freq 1
      pos 10223
  term dy0r84pqebybr7uvlg0up2lhdosdyjczp2ay2tp3596cfdikv51fuz7
    doc 11
      freq 1
      pos 10076
  term dynamic
    doc 6
      freq 5
      pos 514
      pos 632
      pos 1556
      pos 2482
      pos 2922
    doc 10
      freq 1
      pos 13351
    doc 12
      freq 16
      pos 366
      pos 404
      pos 3911
      pos 4408
      pos 4410
      pos 4481
      pos 4526
      pos 5434
      pos 6160
      pos 6393
      pos 6863
      pos 7021
      pos 7117
      pos 7185
      pos 7287
      pos 7302
    doc 14
      freq 3
      pos 92
      pos 300
      pos 2478
    doc 15
      freq 7
      pos 25
      pos 101
      pos 318
      pos 3901
      pos 3951
      pos 3966
      pos 3989
  term dynamically
    doc 0
      freq 14
      pos 3155
      pos 3435
      pos 3606
      pos 4122
      pos 4498
      pos 5455
      pos 8870
      pos 9472
      pos 9655
      pos 9881
      pos 10019
      pos 10963
      pos 11752
      pos 12091
    doc 1
      freq 2
      pos 4355
      pos 8530
    doc 12
      freq 1
      pos 4421
    doc 17
      freq 1
      pos 1328
    doc 18
      freq 1
      pos 759
  term dynamics
    doc 13
      freq 1
      pos 1686
  term dyqeh
    doc 10
      freq 1
      pos 12790
  term e.g
    doc 0
      freq 3
      pos 1419
      pos 10304
      pos 10852
    doc 1
      freq 2
      pos 1075
      pos 1080
    doc 3
      freq 3
      pos 3171
      pos 3816
      pos 3841
    doc 4
      freq 8
      pos 359
      pos 1796
      pos 1952
      pos 2008
      pos 2350
      pos 2409
      pos 2580
      pos 4588
    doc 5
      freq 4
      pos 228
      pos 1254
      pos 1349
      pos 1427
    doc 6
      freq 1
      pos 1232
    doc 9
      freq 1
      pos 511
    doc 10
      freq 8
      pos 928
      pos 3025
      pos 3047
      pos 7447
      pos 7507
      pos 7837
      pos 10624
      pos 11071
    doc 12
      freq 26
      pos 1068
      pos 1385
      pos 1483
      pos 1863
      pos 2053
      pos 2186
      pos 2331
      pos 2409
      pos 2620
      pos 2740
      pos 3362
      pos 4656
      pos 4773
      pos 4858
      pos 4980
      pos 5485
      pos 5772
      pos 5820
      pos 5921
      pos 5970
      pos 6344
      pos 6910
      pos 8026
      pos 9186
      pos 9218
      pos 9239
    doc 13
      freq 15
      pos 521
      pos 624
      pos 779
      pos 1019
      pos 3121
      pos 3559
      pos 3843
      pos 4361
      pos 5628
      pos 5846
      pos 5886
      pos 5912
      pos 5996
      pos 6160
      pos 6626
    doc 14
      freq 7
      pos 728
      pos 763
      pos 940
      pos 1024
      pos 1454
      pos 1676
      pos 2476
    doc 15
      freq 1
      pos 2040
    doc 16
      freq 2
      pos 1117
      pos 1894
    doc 17
      freq 3
      pos 966
      pos 1475
      pos 1484
    doc 18
      freq 3
      pos 555
      pos 727
      pos 1063
    skipList 
      level 0
        skipDoc 10
        skipDocFP 805252
        impacts 
          impact 
            freq 1
            norm 95
          impact 
            freq 4
            norm 104
          impact 
            freq 8
            norm 108
        impactsEnd 
  term e.tasman
    doc 1
      freq 1
      pos 9206
  term e0pom7nlgqylj06
    doc 10
      freq 1
      pos 12474
  term e1
    doc 1
      freq 1
      pos 694
    doc 8
      freq 1
      pos 738
  term e1nmuzimtdlvxywxx4
    doc 10
      freq 1
      pos 12761
  term e1vr
    doc 11
      freq 1
      pos 10384
  term e282ac
    doc 11
      freq 1
      pos 1085
  term e2ojjy21
    doc 11
      freq 1
      pos 10488
  term e3
    doc 1
      freq 1
      pos 696
    doc 8
      freq 1
      pos 753
  term e4
    doc 11
      freq 1
      pos 10411
  term e426xtaisjp
    doc 11
      freq 1
      pos 10389
  term e4fttbqg
    doc 10
      freq 1
      pos 12748
  term e5qyfz69
    doc 11
      freq 1
      pos 10504
  term e7vz
    doc 10
      freq 1
      pos 12649
  term each
    doc 0
      freq 31
      pos 535
      pos 2405
      pos 3144
      pos 3416
      pos 3599
      pos 4107
      pos 4487
      pos 4680
      pos 5366
      pos 5445
      pos 6311
      pos 6314
      pos 7785
      pos 8264
      pos 8798
      pos 8857
      pos 9456
      pos 9639
      pos 9864
      pos 9946
      pos 10006
      pos 10863
      pos 10929
      pos 10942
      pos 10955
      pos 11739
      pos 12010
      pos 12078
      pos 13048
      pos 16192
      pos 16212
    doc 1
      freq 18
      pos 716
      pos 1921
      pos 2191
      pos 2209
      pos 2853
      pos 2918
      pos 3341
      pos 3373
      pos 3451
      pos 3461
      pos 3581
      pos 3996
      pos 5141
      pos 5161
      pos 6007
      pos 6406
      pos 6431
      pos 8841
    doc 2
      freq 4
      pos 796
      pos 1626
      pos 3715
      pos 3957
    doc 3
      freq 4
      pos 864
      pos 941
      pos 1136
      pos 1976
    doc 5
      freq 4
      pos 1645
      pos 1779
      pos 2589
      pos 3758
    doc 6
      freq 2
      pos 1176
      pos 1825
    doc 7
      freq 1
      pos 349
    doc 8
      freq 6
      pos 348
      pos 361
      pos 927
      pos 1252
      pos 1447
      pos 1698
    doc 9
      freq 2
      pos 584
      pos 1157
    doc 10
      freq 8
      pos 4776
      pos 5060
      pos 5062
      pos 5124
      pos 5148
      pos 5693
      pos 8325
      pos 12215
    doc 11
      freq 5
      pos 548
      pos 653
      pos 761
      pos 9734
      pos 9752
    doc 12
      freq 6
      pos 2016
      pos 2059
      pos 2068
      pos 3656
      pos 3921
      pos 4445
    doc 13
      freq 4
      pos 3369
      pos 3429
      pos 3439
      pos 5551
    doc 15
      freq 1
      pos 3874
    doc 16
      freq 2
      pos 733
      pos 1555
    doc 17
      freq 1
      pos 365
    doc 18
      freq 3
      pos 1148
      pos 1158
      pos 1163
    skipList 
      level 0
        skipDoc 8
        skipDocFP 807982
        impacts 
          impact 
            freq 6
            norm 97
          impact 
            freq 18
            norm 113
          impact 
            freq 31
            norm 120
        impactsEnd 
        skipDoc 17
        skipDocFP 809220
        impacts 
          impact 
            freq 2
            norm 95
          impact 
            freq 4
            norm 109
          impact 
            freq 6
            norm 113
          impact 
            freq 8
            norm 116
        impactsEnd 
  term eahb5
    doc 11
      freq 1
      pos 10296
  term eap
    doc 2
      freq 68
      pos 139
      pos 178
      pos 290
      pos 294
      pos 298
      pos 1368
      pos 1385
      pos 1388
      pos 1399
      pos 1404
      pos 1446
      pos 2067
      pos 2074
      pos 2131
      pos 2273
      pos 2284
      pos 2318
      pos 2372
      pos 2809
      pos 2964
      pos 3153
      pos 3278
      pos 3294
      pos 3343
      pos 4837
      pos 4911
      pos 4945
      pos 4960
      pos 4964
      pos 4998
      pos 5017
      pos 5046
      pos 5149
      pos 5156
      pos 5176
      pos 5185
      pos 5190
      pos 5215
      pos 5221
      pos 5229
      pos 5255
      pos 5263
      pos 5334
      pos 5345
      pos 5440
      pos 5474
      pos 5626
      pos 5684
      pos 5713
      pos 5714
      pos 5720
      pos 5727
      pos 5743
      pos 5763
      pos 5764
      pos 5767
      pos 5777
      pos 5789
      pos 5806
      pos 5832
      pos 5841
      pos 5874
      pos 5900
      pos 5907
      pos 5925
      pos 5945
      pos 5983
      pos 6036
  term eapreview
    doc 2
      freq 2
      pos 1439
      pos 2272
  term earlier
    doc 2
      freq 1
      pos 1166
    doc 11
      freq 2
      pos 9457
      pos 9543
  term early
    doc 2
      freq 2
      pos 3673
      pos 4877
    doc 3
      freq 1
      pos 3526
    doc 6
      freq 1
      pos 3169
    doc 11
      freq 2
      pos 7320
      pos 9553
    doc 15
      freq 2
      pos 421
      pos 1363
  term ease
    doc 7
      freq 1
      pos 1460
    doc 12
      freq 1
      pos 2033
  term easier
    doc 12
      freq 2
      pos 2351
      pos 4625
    doc 15
      freq 1
      pos 2982
  term easily
    doc 2
      freq 1
      pos 814
    doc 6
      freq 1
      pos 457
    doc 13
      freq 1
      pos 2334
    doc 15
      freq 1
      pos 3587
    doc 18
      freq 1
      pos 1834
  term east
    doc 1
      freq 1
      pos 9511
    doc 3
      freq 1
      pos 5876
    doc 8
      freq 1
      pos 2135
  term eastlak
    doc 9
      freq 1
      pos 1685
  term easton
    doc 1
      freq 1
      pos 9546
    doc 3
      freq 1
      pos 5911
  term easy
    doc 2
      freq 1
      pos 2172
  term eavesdrop
    doc 5
      freq 1
      pos 3413
  term eb8q
    doc 10
      freq 1
      pos 12735
  term ec0udzilkqqz2q6txqodktul4xnyu1g4oxta95iceeintlmb7gqdqrh0tg7jhdyx
    doc 10
      freq 1
      pos 12605
  term echo
    doc 4
      freq 42
      pos 213
      pos 218
      pos 806
      pos 812
      pos 3543
      pos 3610
      pos 3614
      pos 3643
      pos 3647
      pos 3667
      pos 3672
      pos 3677
      pos 3690
      pos 3694
      pos 3702
      pos 3714
      pos 3773
      pos 3788
      pos 3814
      pos 3823
      pos 3833
      pos 3838
      pos 3843
      pos 3856
      pos 3860
      pos 3870
      pos 3878
      pos 3891
      pos 3895
      pos 3904
      pos 3936
      pos 3947
      pos 3959
      pos 3965
      pos 3977
      pos 3981
      pos 3994
      pos 4013
      pos 4016
      pos 5782
      pos 5790
      pos 5795
  term echoing
    doc 7
      freq 1
      pos 1845
  term eci
    doc 1
      freq 2
      pos 9252
      pos 9268
    doc 3
      freq 1
      pos 4782
  term ecitele.com
    doc 1
      freq 2
      pos 9265
      pos 9281
    doc 3
      freq 1
      pos 4795
  term ecmp
    doc 3
      freq 4
      pos 3304
      pos 3345
      pos 3360
      pos 3491
  term economical
    doc 6
      freq 1
      pos 800
    doc 14
      freq 2
      pos 477
      pos 1170
  term economy
    doc 14
      freq 1
      pos 580
  term ecp
    doc 7
      freq 1
      pos 2839
  term ecs.soton.ac.uk
    doc 15
      freq 1
      pos 4035
  term edge
    doc 1
      freq 12
      pos 1037
      pos 1040
      pos 1044
      pos 1046
      pos 2526
      pos 2528
      pos 6090
      pos 6092
      pos 8960
      pos 8962
      pos 9156
      pos 9158
    doc 3
      freq 16
      pos 446
      pos 448
      pos 508
      pos 527
      pos 612
      pos 615
      pos 619
      pos 621
      pos 4320
      pos 4322
      pos 4343
      pos 4345
      pos 4523
      pos 4525
      pos 4581
      pos 4583
    doc 8
      freq 6
      pos 24
      pos 26
      pos 89
      pos 91
      pos 2111
      pos 2113
    doc 11
      freq 2
      pos 4195
      pos 9331
  term edges
    doc 1
      freq 2
      pos 3985
      pos 5996
    doc 3
      freq 1
      pos 1965
  term edi
    doc 7
      freq 1
      pos 2693
  term edited
    doc 4
      freq 1
      pos 5552
    doc 10
      freq 1
      pos 12427
    doc 11
      freq 1
      pos 9834
    doc 16
      freq 1
      pos 1877
  term edition
    doc 0
      freq 1
      pos 56
    doc 1
      freq 1
      pos 73
    doc 2
      freq 1
      pos 3427
    doc 3
      freq 2
      pos 67
      pos 4471
    doc 4
      freq 1
      pos 69
    doc 5
      freq 1
      pos 53
    doc 9
      freq 1
      pos 55
    doc 10
      freq 1
      pos 58
    doc 16
      freq 1
      pos 54
    doc 17
      freq 1
      pos 51
    doc 18
      freq 1
      pos 60
    skipList 
      level 0
        skipDoc 10
        skipDocFP 815236
        impacts 
          impact 
            freq 1
            norm 95
          impact 
            freq 2
            norm 107
        impactsEnd 
  term editor
    doc 0
      freq 1
      pos 17531
    doc 1
      freq 1
      pos 9912
    doc 2
      freq 4
      pos 4478
      pos 4484
      pos 4568
      pos 6709
    doc 3
      freq 2
      pos 5871
      pos 6261
    doc 4
      freq 3
      pos 4994
      pos 5519
      pos 6416
    doc 5
      freq 1
      pos 4746
    doc 6
      freq 2
      pos 144
      pos 3546
    doc 7
      freq 3
      pos 299
      pos 1589
      pos 3251
    doc 8
      freq 1
      pos 2468
    doc 9
      freq 1
      pos 2113
    doc 10
      freq 1
      pos 13774
    doc 11
      freq 2
      pos 10529
      pos 10935
    doc 12
      freq 1
      pos 9785
    doc 13
      freq 1
      pos 7400
    doc 14
      freq 1
      pos 5866
    doc 15
      freq 1
      pos 4385
    doc 16
      freq 1
      pos 2996
    doc 17
      freq 1
      pos 2720
    doc 18
      freq 1
      pos 2508
    skipList 
      level 0
        skipDoc 7
        skipDocFP 815891
        impacts 
          impact 
            freq 3
            norm 100
          impact 
            freq 4
            norm 108
        impactsEnd 
        skipDoc 15
        skipDocFP 816329
        impacts 
          impact 
            freq 1
            norm 95
          impact 
            freq 2
            norm 114
        impactsEnd 
  term editor.org
    doc 6
      freq 1
      pos 3259
  term editorial
    doc 4
      freq 1
      pos 5764
    doc 10
      freq 2
      pos 6478
      pos 7228
  term editors
    doc 2
      freq 4
      pos 3903
      pos 4048
      pos 4761
      pos 4799
    doc 18
      freq 1
      pos 2037
  term edns0
    doc 12
      freq 2
      pos 7093
      pos 9327
  term edu
    doc 0
      freq 1
      pos 1120
  term edward
    doc 12
      freq 1
      pos 6811
  term eerx35elxrpff5gzq
    doc 10
      freq 1
      pos 12522
  term efbbbfe5a4a7e5819ce99bbb
    doc 11
      freq 1
      pos 1996
  term eff
    doc 10
      freq 1
      pos 12747
  term effect
    doc 0
      freq 1
      pos 16156
    doc 10
      freq 1
      pos 9786
    doc 12
      freq 1
      pos 657
    doc 14
      freq 2
      pos 2111
      pos 2457
    doc 15
      freq 1
      pos 2132
    doc 18
      freq 1
      pos 290
  term effectiv
    doc 0
      freq 2
      pos 10635
      pos 10756
    doc 10
      freq 1
      pos 4340
    doc 12
      freq 1
      pos 1853
    doc 13
      freq 1
      pos 2349
    doc 14
      freq 3
      pos 196
      pos 2350
      pos 2491
  term effectively
    doc 10
      freq 1
      pos 11067
    doc 13
      freq 1
      pos 3419
    doc 14
      freq 2
      pos 2410
      pos 2750
    doc 18
      freq 1
      pos 128
  term effectiveness
    doc 6
      freq 1
      pos 464
    doc 14
      freq 1
      pos 5293
  term effects
    doc 0
      freq 1
      pos 16199
    doc 6
      freq 1
      pos 906
  term efficiency
    doc 9
      freq 1
      pos 482
  term efficient
    doc 5
      freq 6
      pos 19
      pos 89
      pos 104
      pos 4195
      pos 4220
      pos 4265
    doc 10
      freq 1
      pos 4033
    doc 13
      freq 3
      pos 112
      pos 2359
      pos 5401
  term effort
    doc 0
      freq 1
      pos 17396
    doc 1
      freq 1
      pos 9777
    doc 2
      freq 2
      pos 807
      pos 6574
    doc 3
      freq 4
      pos 3873
      pos 5690
      pos 5730
      pos 6126
    doc 4
      freq 1
      pos 6281
    doc 5
      freq 1
      pos 4611
    doc 6
      freq 1
      pos 3411
    doc 7
      freq 2
      pos 288
      pos 3116
    doc 8
      freq 1
      pos 2333
    doc 9
      freq 3
      pos 451
      pos 639
      pos 1978
    doc 10
      freq 1
      pos 13639
    doc 11
      freq 1
      pos 10800
    doc 12
      freq 1
      pos 9650
    doc 13
      freq 1
      pos 7265
    doc 14
      freq 1
      pos 5731
    doc 15
      freq 2
      pos 3419
      pos 4250
    doc 16
      freq 1
      pos 2861
    doc 17
      freq 1
      pos 2585
    doc 18
      freq 1
      pos 2373
    skipList 
      level 0
        skipDoc 7
        skipDocFP 819048
        impacts 
          impact 
            freq 2
            norm 100
          impact 
            freq 4
            norm 107
        impactsEnd 
        skipDoc 15
        skipDocFP 819426
        impacts 
          impact 
            freq 3
            norm 95
        impactsEnd 
  term efg
    doc 10
      freq 1
      pos 12679
  term efqs33evlbh
    doc 11
      freq 1
      pos 10362
  term egress
    doc 1
      freq 9
      pos 1130
      pos 1205
      pos 1720
      pos 1739
      pos 2686
      pos 3981
      pos 4361
      pos 5992
      pos 6160
    doc 3
      freq 9
      pos 786
      pos 1397
      pos 1491
      pos 1729
      pos 1961
      pos 2869
      pos 3572
      pos 3830
      pos 5055
    doc 4
      freq 4
      pos 2196
      pos 2620
      pos 5112
      pos 5700
    doc 8
      freq 2
      pos 1609
      pos 1627
  term ehpywfswtnzwymunnxldkkllus0omlc7tfmwhw
    doc 11
      freq 1
      pos 9933
  term eidnes
    doc 12
      freq 1
      pos 6769
  term eight
    doc 14
      freq 1
      pos 4429
  term eighth
    doc 12
      freq 1
      pos 710
  term eigrp
    doc 0
      freq 1
      pos 11667
  term eihu51myjrublihkpuwjbwtdkjjj0mqzlpqpjmvg40i2hhahdtntch08zdpasgdm
    doc 10
      freq 1
      pos 12576
  term either
    doc 0
      freq 1
      pos 10907
    doc 1
      freq 5
      pos 3167
      pos 5414
      pos 6669
      pos 7015
      pos 8510
    doc 2
      freq 3
      pos 3810
      pos 4528
      pos 5679
    doc 3
      freq 2
      pos 1444
      pos 1523
    doc 4
      freq 3
      pos 1617
      pos 1909
      pos 3160
    doc 7
      freq 3
      pos 572
      pos 1213
      pos 1622
    doc 10
      freq 3
      pos 1606
      pos 11329
      pos 11675
    doc 11
      freq 1
      pos 7712
    doc 12
      freq 8
      pos 2319
      pos 2920
      pos 3906
      pos 4966
      pos 6072
      pos 8269
      pos 8728
      pos 8860
    doc 13
      freq 4
      pos 2971
      pos 2998
      pos 3260
      pos 4754
    doc 14
      freq 2
      pos 1802
      pos 2318
    doc 15
      freq 2
      pos 1140
      pos 2229
    doc 17
      freq 1
      pos 432
    skipList 
      level 0
        skipDoc 11
        skipDocFP 821255
        impacts 
          impact 
            freq 3
            norm 100
          impact 
            freq 5
            norm 113
        impactsEnd 
  term ek4
    doc 10
      freq 1
      pos 12777
  term ekewgf5fnppwv2s7a3zg17
    doc 11
      freq 1
      pos 9980
  term ekzrow5vsfzry3svp9ch3f8ehsze
    doc 11
      freq 1
      pos 10140
  term el
    doc 1
      freq 4
      pos 19
      pos 9052
      pos 9102
      pos 9523
    doc 3
      freq 3
      pos 19
      pos 4358
      pos 5888
    doc 8
      freq 3
      pos 1790
      pos 1941
      pos 1989
  term elaborat
    doc 4
      freq 1
      pos 5561
    doc 13
      freq 1
      pos 498
  term elaborated
    doc 12
      freq 1
      pos 7987
  term elapsed
    doc 0
      freq 3
      pos 5087
      pos 5125
      pos 9277
  term elapses
    doc 13
      freq 4
      pos 805
      pos 2862
      pos 3481
      pos 4717
  term eldorad
    doc 1
      freq 1
      pos 9530
    doc 3
      freq 1
      pos 5895
  term elected
    doc 0
      freq 1
      pos 6580
    doc 2
      freq 1
      pos 6134
  term electing
    doc 0
      freq 1
      pos 1480
  term election
    doc 0
      freq 1
      pos 6758
  term electrical
    doc 2
      freq 1
      pos 2394
  term electronic
    doc 7
      freq 8
      pos 800
      pos 815
      pos 829
      pos 843
      pos 2210
      pos 2225
      pos 2239
      pos 2253
    doc 13
      freq 3
      pos 473
      pos 582
      pos 2954
  term electronics
    doc 2
      freq 1
      pos 2396
    doc 15
      freq 1
      pos 4023
  term element
    doc 1
      freq 38
      pos 252
      pos 259
      pos 271
      pos 2217
      pos 2317
      pos 2322
      pos 2390
      pos 2394
      pos 2436
      pos 2441
      pos 2896
      pos 2900
      pos 2930
      pos 2979
      pos 2988
      pos 3002
      pos 3031
      pos 3593
      pos 3622
      pos 3624
      pos 3631
      pos 3853
      pos 4301
      pos 4398
      pos 4405
      pos 5451
      pos 5464
      pos 5500
      pos 5532
      pos 7106
      pos 7119
      pos 7156
      pos 7208
      pos 7299
      pos 7309
      pos 7907
      pos 8756
      pos 8799
    doc 6
      freq 1
      pos 2960
    doc 11
      freq 44
      pos 1399
      pos 3270
      pos 3293
      pos 4256
      pos 4379
      pos 4538
      pos 4792
      pos 4818
      pos 4840
      pos 5009
      pos 5100
      pos 5112
      pos 5126
      pos 5294
      pos 5417
      pos 5429
      pos 5578
      pos 5598
      pos 5744
      pos 5764
      pos 5864
      pos 5875
      pos 5892
      pos 6065
      pos 6084
      pos 6301
      pos 6313
      pos 6535
      pos 6552
      pos 6643
      pos 6657
      pos 6749
      pos 6822
      pos 6952
      pos 7056
      pos 7182
      pos 7305
      pos 7452
      pos 7482
      pos 7691
      pos 7727
      pos 8099
      pos 8107
      pos 8268
    doc 13
      freq 3
      pos 1245
      pos 1249
      pos 5481
  term elements
    doc 0
      freq 5
      pos 3625
      pos 4141
      pos 10982
      pos 14115
      pos 16929
    doc 1
      freq 6
      pos 757
      pos 2201
      pos 3794
      pos 3801
      pos 3812
      pos 8128
    doc 6
      freq 1
      pos 1681
    doc 10
      freq 3
      pos 276
      pos 4882
      pos 8213
    doc 11
      freq 11
      pos 309
      pos 1350
      pos 1598
      pos 2663
      pos 3480
      pos 3588
      pos 5277
      pos 5554
      pos 5563
      pos 6422
      pos 9170
    doc 13
      freq 2
      pos 1266
      pos 1279
    doc 15
      freq 1
      pos 3030
    doc 16
      freq 1
      pos 1425
    skipList 
      level 0
        skipDoc 16
        skipDocFP 825188
        impacts 
          impact 
            freq 1
            norm 99
          impact 
            freq 2
            norm 109
          impact 
            freq 6
            norm 113
          impact 
            freq 11
            norm 114
        impactsEnd 
  term eligibl
    doc 1
      freq 10
      pos 8498
      pos 8504
      pos 8552
      pos 8571
      pos 8597
      pos 8742
      pos 8772
      pos 8812
      pos 8851
      pos 8861
    doc 10
      freq 2
      pos 1079
      pos 8774
  term eliminat
    doc 1
      freq 1
      pos 8615
    doc 10
      freq 1
      pos 9185
    doc 14
      freq 1
      pos 1351
  term eliminates
    doc 1
      freq 1
      pos 8660
  term eliot
    doc 7
      freq 1
      pos 2898
  term else
    doc 1
      freq 2
      pos 5426
      pos 8461
    doc 14
      freq 2
      pos 1980
      pos 2002
  term else's
    doc 10
      freq 1
      pos 9378
  term elsewher
    doc 4
      freq 1
      pos 2048
    doc 12
      freq 1
      pos 6255
    doc 13
      freq 1
      pos 653
  term elwell
    doc 10
      freq 1
      pos 12130
  term elwyn
    doc 4
      freq 1
      pos 5503
  term elz
    doc 4
      freq 1
      pos 5473
    doc 12
      freq 2
      pos 7035
      pos 7050
    doc 14
      freq 1
      pos 5391
    doc 15
      freq 1
      pos 3852
  term email
    doc 0
      freq 1
      pos 17208
    doc 1
      freq 17
      pos 9197
      pos 9214
      pos 9247
      pos 9263
      pos 9279
      pos 9294
      pos 9308
      pos 9321
      pos 9350
      pos 9363
      pos 9377
      pos 9391
      pos 9519
      pos 9535
      pos 9554
      pos 9569
      pos 9587
    doc 2
      freq 1
      pos 6386
    doc 3
      freq 19
      pos 4763
      pos 4777
      pos 4793
      pos 4809
      pos 4822
      pos 4853
      pos 4867
      pos 4882
      pos 4897
      pos 4912
      pos 4926
      pos 4956
      pos 4970
      pos 4984
      pos 4991
      pos 5884
      pos 5900
      pos 5919
      pos 5934
    doc 4
      freq 2
      pos 6055
      pos 6090
    doc 5
      freq 2
      pos 4409
      pos 4423
    doc 6
      freq 2
      pos 3195
      pos 3215
    doc 7
      freq 2
      pos 2915
      pos 2929
    doc 8
      freq 1
      pos 2143
    doc 9
      freq 1
      pos 1788
    doc 10
      freq 4
      pos 9596
      pos 9710
      pos 13423
      pos 13451
    doc 11
      freq 5
      pos 10532
      pos 10551
      pos 10561
      pos 10579
      pos 10607
    doc 12
      freq 3
      pos 9438
      pos 9451
      pos 9460
    doc 13
      freq 5
      pos 7004
      pos 7019
      pos 7035
      pos 7054
      pos 7073
    doc 14
      freq 2
      pos 5523
      pos 5541
    doc 15
      freq 3
      pos 4033
      pos 4043
      pos 4059
    doc 16
      freq 1
      pos 2669
    doc 17
      freq 2
      pos 2381
      pos 2396
    doc 18
      freq 2
      pos 2171
      pos 2185
    skipList 
      level 0
        skipDoc 7
        skipDocFP 827253
        impacts 
          impact 
            freq 2
            norm 100
          impact 
            freq 19
            norm 107
        impactsEnd 
        skipDoc 15
        skipDocFP 828130
        impacts 
          impact 
            freq 1
            norm 95
          impact 
            freq 3
            norm 104
          impact 
            freq 5
            norm 109
        impactsEnd 
  term emanating
    doc 9
      freq 1
      pos 1511
  term embedded
    doc 0
      freq 5
      pos 10326
      pos 10401
      pos 10415
      pos 10640
      pos 10769
    doc 4
      freq 2
      pos 2015
      pos 5629
    doc 11
      freq 4
      pos 300
      pos 2037
      pos 5405
      pos 5435
    doc 12
      freq 2
      pos 1537
      pos 1543
  term emcdbk
    doc 10
      freq 1
      pos 12581
  term emission
    doc 0
      freq 1
      pos 2996
  term emphasiz
    doc 12
      freq 1
      pos 6942
  term employ
    doc 3
      freq 1
      pos 3349
    doc 10
      freq 1
      pos 11155
    doc 17
      freq 1
      pos 1686
  term employed
    doc 0
      freq 2
      pos 10256
      pos 16173
    doc 10
      freq 3
      pos 446
      pos 522
      pos 1711
  term employees
    doc 2
      freq 1
      pos 1187
  term employing
    doc 6
      freq 1
      pos 467
  term empty
    doc 0
      freq 3
      pos 12624
      pos 14142
      pos 14154
    doc 10
      freq 2
      pos 5186
      pos 5273
    doc 11
      freq 3
      pos 240
      pos 1223
      pos 4079
    doc 18
      freq 1
      pos 1331
  term emulat
    doc 1
      freq 2
      pos 618
      pos 686
    doc 3
      freq 1
      pos 705
  term emulated
    doc 1
      freq 9
      pos 120
      pos 232
      pos 1011
      pos 1013
      pos 1071
      pos 1073
      pos 1078
      pos 1979
      pos 2180
    doc 3
      freq 13
      pos 124
      pos 196
      pos 513
      pos 570
      pos 588
      pos 644
      pos 683
      pos 692
      pos 721
      pos 722
      pos 726
      pos 849
      pos 1692
  term emulates
    doc 3
      freq 1
      pos 816
  term emulating
    doc 1
      freq 1
      pos 8068
  term emulation
    doc 1
      freq 8
      pos 159
      pos 574
      pos 665
      pos 2529
      pos 6093
      pos 8963
      pos 8988
      pos 9155
    doc 3
      freq 8
      pos 445
      pos 1029
      pos 1269
      pos 1295
      pos 4319
      pos 4346
      pos 4522
      pos 4580
    doc 8
      freq 6
      pos 27
      pos 668
      pos 731
      pos 1878
      pos 2026
      pos 2110
  term en
    doc 16
      freq 4
      pos 1999
      pos 2001
      pos 2367
      pos 2369
  term enabl
    doc 0
      freq 1
      pos 16818
    doc 1
      freq 3
      pos 764
      pos 7953
      pos 8293
    doc 2
      freq 3
      pos 815
      pos 984
      pos 997
    doc 5
      freq 1
      pos 2471
    doc 12
      freq 1
      pos 4215
    doc 13
      freq 10
      pos 1290
      pos 1922
      pos 2123
      pos 2181
      pos 2237
      pos 2357
      pos 3177
      pos 4073
      pos 5193
      pos 5398
    doc 18
      freq 1
      pos 1723
  term enabled
    doc 0
      freq 9
      pos 571
      pos 3998
      pos 4047
      pos 4067
      pos 6148
      pos 6201
      pos 8473
      pos 8535
      pos 8592
    doc 1
      freq 13
      pos 163
      pos 460
      pos 580
      pos 1212
      pos 4832
      pos 6176
      pos 6212
      pos 6356
      pos 7445
      pos 7664
      pos 8074
      pos 8134
      pos 8220
    doc 2
      freq 1
      pos 5340
    doc 3
      freq 6
      pos 1635
      pos 2099
      pos 2845
      pos 2983
      pos 3017
      pos 3091
    doc 12
      freq 12
      pos 283
      pos 1123
      pos 2316
      pos 2520
      pos 2601
      pos 2668
      pos 3227
      pos 3296
      pos 3346
      pos 3730
      pos 3775
      pos 3864
  term enables
    doc 0
      freq 2
      pos 2752
      pos 2994
    doc 1
      freq 2
      pos 509
      pos 4172
    doc 3
      freq 1
      pos 119
    doc 5
      freq 1
      pos 400
    doc 13
      freq 3
      pos 2279
      pos 2288
      pos 3741
  term enabling
    doc 0
      freq 1
      pos 1590
    doc 9
      freq 1
      pos 560
    doc 12
      freq 2
      pos 2789
      pos 3276
    doc 13
      freq 4
      pos 2747
      pos 3041
      pos 3203
      pos 3322
    doc 14
      freq 1
      pos 97
  term encap
    doc 3
      freq 2
      pos 5044
      pos 5051
  term encapsulat
    doc 1
      freq 2
      pos 447
      pos 722
  term encapsulated
    doc 1
      freq 4
      pos 479
      pos 632
      pos 1141
      pos 7959
    doc 3
      freq 8
      pos 797
      pos 1703
      pos 1851
      pos 2873
      pos 3023
      pos 4201
      pos 4247
      pos 4268
    doc 8
      freq 1
      pos 1693
    doc 11
      freq 1
      pos 764
  term encapsulating
    doc 1
      freq 4
      pos 126
      pos 185
      pos 705
      pos 1242
    doc 3
      freq 3
      pos 1104
      pos 3814
      pos 3839
    doc 4
      freq 9
      pos 4045
      pos 4064
      pos 4226
      pos 4252
      pos 4275
      pos 4290
      pos 4304
      pos 5413
      pos 5833
  term encapsulation
    doc 1
      freq 11
      pos 649
      pos 1085
      pos 1087
      pos 1275
      pos 1995
      pos 2018
      pos 6156
      pos 9035
      pos 9059
      pos 9081
      pos 9108
    doc 2
      freq 1
      pos 4996
    doc 3
      freq 32
      pos 30
      pos 135
      pos 169
      pos 334
      pos 581
      pos 761
      pos 1009
      pos 1040
      pos 1426
      pos 1779
      pos 2118
      pos 2198
      pos 2216
      pos 2236
      pos 2284
      pos 2429
      pos 2824
      pos 2891
      pos 3208
      pos 3617
      pos 4011
      pos 4212
      pos 4299
      pos 4560
      pos 4741
      pos 4834
      pos 4938
      pos 5003
      pos 5199
      pos 5589
      pos 5790
      pos 5946
    doc 6
      freq 1
      pos 825
    doc 7
      freq 2
      pos 2618
      pos 2691
    doc 8
      freq 4
      pos 1910
      pos 1948
      pos 1970
      pos 1995
    doc 15
      freq 1
      pos 2521
  term encapsulations
    doc 1
      freq 3
      pos 8288
      pos 8330
      pos 8367
  term encapsulator
    doc 1
      freq 1
      pos 8299
  term enclos
    doc 11
      freq 2
      pos 339
      pos 6255
  term enclosed
    doc 11
      freq 2
      pos 5258
      pos 6294
  term enclosing
    doc 11
      freq 2
      pos 291
      pos 5244
  term encod
    doc 10
      freq 1
      pos 5526
  term encoded
    doc 1
      freq 1
      pos 3633
    doc 6
      freq 2
      pos 637
      pos 674
    doc 8
      freq 1
      pos 1503
    doc 10
      freq 4
      pos 373
      pos 12191
      pos 12423
      pos 12447
    doc 11
      freq 9
      pos 554
      pos 858
      pos 1015
      pos 1740
      pos 2145
      pos 3710
      pos 9743
      pos 9830
      pos 9868
    doc 13
      freq 1
      pos 1902
    doc 16
      freq 1
      pos 964
  term encoding
    doc 0
      freq 3
      pos 2042
      pos 2077
      pos 10349
    doc 1
      freq 3
      pos 266
      pos 3617
      pos 8948
    doc 5
      freq 2
      pos 270
      pos 1483
    doc 7
      freq 1
      pos 2044
    doc 8
      freq 1
      pos 2073
    doc 10
      freq 3
      pos 6555
      pos 7260
      pos 12262
    doc 11
      freq 3
      pos 3831
      pos 3863
      pos 3874
    doc 12
      freq 1
      pos 7832
    doc 16
      freq 3
      pos 1162
      pos 2040
      pos 2218
    skipList 
      level 0
        skipDoc 12
        skipDocFP 835923
        impacts 
          impact 
            freq 1
            norm 97
          impact 
            freq 2
            norm 104
          impact 
            freq 3
            norm 113
        impactsEnd 
  term encodings
    doc 10
      freq 1
      pos 13221
    doc 16
      freq 1
      pos 1120
  term encountered
    doc 1
      freq 1
      pos 6128
    doc 4
      freq 5
      pos 485
      pos 3319
      pos 3325
      pos 3330
      pos 4661
  term encounters
    doc 1
      freq 1
      pos 5368
    doc 11
      freq 1
      pos 5139
  term encourag
    doc 2
      freq 2
      pos 317
      pos 1219
  term encouraged
    doc 2
      freq 2
      pos 1163
      pos 1578
    doc 7
      freq 1
      pos 560
    doc 17
      freq 1
      pos 1677
    doc 18
      freq 2
      pos 365
      pos 492
  term encouraging
    doc 12
      freq 1
      pos 7846
  term encrypted
    doc 6
      freq 1
      pos 2851
    doc 7
      freq 1
      pos 2767
  term encryption
    doc 4
      freq 1
      pos 4340
    doc 5
      freq 4
      pos 777
      pos 780
      pos 3649
      pos 3665
    doc 7
      freq 3
      pos 805
      pos 2215
      pos 2836
    doc 13
      freq 1
      pos 2413
  term end
    doc 0
      freq 1
      pos 15793
    doc 1
      freq 4
      pos 863
      pos 3092
      pos 3103
      pos 7966
    doc 2
      freq 1
      pos 4263
    doc 3
      freq 8
      pos 594
      pos 600
      pos 865
      pos 962
      pos 3962
      pos 5246
      pos 5272
      pos 5306
    doc 4
      freq 2
      pos 2011
      pos 3351
    doc 5
      freq 2
      pos 3592
      pos 3594
    doc 6
      freq 2
      pos 1174
      pos 1404
    doc 7
      freq 1
      pos 1880
    doc 10
      freq 25
      pos 110
      pos 553
      pos 1425
      pos 1427
      pos 1503
      pos 1505
      pos 1542
      pos 1624
      pos 1626
      pos 1633
      pos 1655
      pos 1677
      pos 4664
      pos 6242
      pos 6285
      pos 6873
      pos 6914
      pos 6930
      pos 8948
      pos 9136
      pos 9138
      pos 9249
      pos 9916
      pos 12406
      pos 12822
    doc 11
      freq 6
      pos 315
      pos 841
      pos 924
      pos 5712
      pos 9811
      pos 10507
    doc 13
      freq 3
      pos 2975
      pos 6118
      pos 6120
    doc 16
      freq 1
      pos 645
    doc 17
      freq 1
      pos 2364
    skipList 
      level 0
        skipDoc 7
        skipDocFP 837733
        impacts 
          impact 
            freq 1
            norm 100
          impact 
            freq 2
            norm 101
          impact 
            freq 8
            norm 107
        impactsEnd 
  term ending
    doc 2
      freq 1
      pos 3940
  term endpoint
    doc 1
      freq 14
      pos 501
      pos 530
      pos 780
      pos 801
      pos 1922
      pos 1934
      pos 2919
      pos 2952
      pos 3452
      pos 3562
      pos 4435
      pos 6409
      pos 7016
      pos 7042
    doc 3
      freq 1
      pos 3001
    doc 10
      freq 3
      pos 1737
      pos 3455
      pos 3518
    doc 11
      freq 4
      pos 2528
      pos 7829
      pos 8410
      pos 8583
  term endpoints
    doc 1
      freq 11
      pos 885
      pos 1840
      pos 2401
      pos 2762
      pos 2858
      pos 2935
      pos 2948
      pos 2965
      pos 3314
      pos 3441
      pos 6998
    doc 3
      freq 1
      pos 824
    doc 11
      freq 3
      pos 1426
      pos 1875
      pos 8002
    doc 18
      freq 1
      pos 1054
  term ends
    doc 3
      freq 3
      pos 1517
      pos 1766
      pos 2863
  term energy
    doc 10
      freq 1
      pos 9361
  term enforc
    doc 10
      freq 1
      pos 9755
  term enforced
    doc 10
      freq 1
      pos 9829
  term enforcement
    doc 10
      freq 1
      pos 9953
  term engineered
    doc 18
      freq 1
      pos 1836
  term engineering
    doc 0
      freq 4
      pos 1767
      pos 1811
      pos 5212
      pos 17292
    doc 1
      freq 1
      pos 9673
    doc 2
      freq 3
      pos 350
      pos 423
      pos 6470
    doc 3
      freq 1
      pos 6022
    doc 4
      freq 1
      pos 6177
    doc 5
      freq 1
      pos 4507
    doc 6
      freq 1
      pos 3307
    doc 7
      freq 1
      pos 3012
    doc 8
      freq 1
      pos 2229
    doc 9
      freq 1
      pos 1874
    doc 10
      freq 1
      pos 13535
    doc 11
      freq 1
      pos 10696
    doc 12
      freq 1
      pos 9546
    doc 13
      freq 1
      pos 7161
    doc 14
      freq 1
      pos 5627
    doc 15
      freq 1
      pos 4146
    doc 16
      freq 1
      pos 2757
    doc 17
      freq 1
      pos 2481
    doc 18
      freq 1
      pos 2269
    skipList 
      level 0
        skipDoc 7
        skipDocFP 840382
        impacts 
          impact 
            freq 1
            norm 100
          impact 
            freq 3
            norm 108
          impact 
            freq 4
            norm 120
        impactsEnd 
        skipDoc 15
        skipDocFP 840760
        impacts 
          impact 
            freq 1
            norm 95
        impactsEnd 
  term engineers
    doc 2
      freq 1
      pos 2397
  term engines
    doc 13
      freq 1
      pos 2825
  term englewood
    doc 1
      freq 1
      pos 9516
    doc 3
      freq 1
      pos 5881
    doc 8
      freq 1
      pos 2140
  term enhanced
    doc 2
      freq 2
      pos 2687
      pos 3721
    doc 5
      freq 2
      pos 540
      pos 837
    doc 14
      freq 1
      pos 5302
  term enhancement
    doc 5
      freq 1
      pos 1522
    doc 7
      freq 8
      pos 797
      pos 812
      pos 826
      pos 840
      pos 2207
      pos 2222
      pos 2236
      pos 2250
  term enhancements
    doc 2
      freq 1
      pos 5639
    doc 5
      freq 1
      pos 645
    doc 10
      freq 2
      pos 19
      pos 407
  term enleocim8n9t
    doc 11
      freq 1
      pos 10370
  term enormous
    doc 12
      freq 1
      pos 1813
  term enough
    doc 3
      freq 1
      pos 4190
    doc 5
      freq 1
      pos 2115
    doc 6
      freq 3
      pos 1089
      pos 1419
      pos 1455
    doc 12
      freq 3
      pos 2498
      pos 6659
      pos 8780
  term enrollment
    doc 10
      freq 2
      pos 9668
      pos 9922
  term ensur
    doc 0
      freq 2
      pos 2155
      pos 16829
    doc 1
      freq 1
      pos 8370
    doc 2
      freq 4
      pos 543
      pos 1311
      pos 4903
      pos 5576
    doc 9
      freq 3
      pos 1061
      pos 1126
      pos 1169
    doc 10
      freq 4
      pos 3146
      pos 3176
      pos 4282
      pos 13014
    doc 12
      freq 4
      pos 1126
      pos 2227
      pos 3238
      pos 5718
    doc 13
      freq 2
      pos 5407
      pos 6115
    doc 14
      freq 1
      pos 2488
    doc 15
      freq 1
      pos 2224
    doc 17
      freq 2
      pos 1308
      pos 1856
    doc 18
      freq 1
      pos 1268
    skipList 
      level 0
        skipDoc 14
        skipDocFP 842777
        impacts 
          impact 
            freq 3
            norm 95
          impact 
            freq 4
            norm 108
        impactsEnd 
  term ensured
    doc 9
      freq 1
      pos 288
  term ensures
    doc 9
      freq 1
      pos 1181
  term ensuring
    doc 12
      freq 2
      pos 5050
      pos 5076
  term entails
    doc 10
      freq 1
      pos 7956
  term entered
    doc 0
      freq 1
      pos 9334
    doc 2
      freq 1
      pos 6260
  term entering
    doc 0
      freq 2
      pos 2683
      pos 14216
    doc 9
      freq 1
      pos 1254
    doc 12
      freq 1
      pos 9297
  term enterpris
    doc 4
      freq 1
      pos 6049
    doc 12
      freq 1
      pos 2412
  term enters
    doc 0
      freq 1
      pos 12802
    doc 1
      freq 1
      pos 8317
  term entir
    doc 0
      freq 1
      pos 10766
    doc 4
      freq 1
      pos 1271
    doc 5
      freq 1
      pos 3477
    doc 16
      freq 1
      pos 124
  term entirely
    doc 1
      freq 1
      pos 4860
    doc 3
      freq 1
      pos 2721
    doc 4
      freq 1
      pos 3953
    doc 10
      freq 1
      pos 9187
    doc 14
      freq 1
      pos 1740
  term entirety
    doc 3
      freq 1
      pos 1378
  term entities
    doc 5
      freq 9
      pos 686
      pos 745
      pos 1426
      pos 2864
      pos 2925
      pos 2940
      pos 3298
      pos 3310
      pos 3346
    doc 9
      freq 1
      pos 218
    doc 10
      freq 7
      pos 1311
      pos 2106
      pos 2176
      pos 2237
      pos 2318
      pos 3803
      pos 4017
    doc 13
      freq 4
      pos 4495
      pos 6401
      pos 6432
      pos 6453
  term entity
    doc 0
      freq 3
      pos 1424
      pos 2414
      pos 16833
    doc 3
      freq 1
      pos 5155
    doc 5
      freq 2
      pos 678
      pos 701
    doc 10
      freq 6
      pos 915
      pos 2127
      pos 2219
      pos 3910
      pos 4573
      pos 11179
    doc 13
      freq 5
      pos 1346
      pos 1365
      pos 4220
      pos 6474
      pos 6488
  term entries
    doc 0
      freq 3
      pos 743
      pos 5393
      pos 10949
    doc 10
      freq 3
      pos 5775
      pos 11972
      pos 12055
  term entry
    doc 0
      freq 28
      pos 3145
      pos 3198
      pos 3300
      pos 3417
      pos 3600
      pos 3907
      pos 4108
      pos 4419
      pos 4488
      pos 4748
      pos 5379
      pos 5703
      pos 6394
      pos 7299
      pos 8806
      pos 8858
      pos 9457
      pos 9640
      pos 9705
      pos 9865
      pos 9947
      pos 10007
      pos 10138
      pos 10864
      pos 10930
      pos 11437
      pos 11740
      pos 12079
    doc 1
      freq 2
      pos 1499
      pos 1526
    doc 4
      freq 1
      pos 2292
    doc 7
      freq 1
      pos 1920
    doc 10
      freq 2
      pos 11950
      pos 12032
  term enum
    doc 10
      freq 2
      pos 7726
      pos 13357
  term enumerat
    doc 13
      freq 1
      pos 1526
    doc 14
      freq 1
      pos 2658
  term envelop
    doc 13
      freq 8
      pos 645
      pos 5303
      pos 5319
      pos 5334
      pos 5359
      pos 5489
      pos 5538
      pos 5549
  term environment
    doc 0
      freq 1
      pos 16148
    doc 3
      freq 1
      pos 4159
    doc 5
      freq 1
      pos 2753
    doc 7
      freq 1
      pos 2507
    doc 13
      freq 2
      pos 3792
      pos 4940
    doc 15
      freq 14
      pos 383
      pos 458
      pos 521
      pos 572
      pos 597
      pos 603
      pos 712
      pos 732
      pos 1078
      pos 1130
      pos 1190
      pos 1432
      pos 2275
      pos 2679
    doc 17
      freq 1
      pos 1191
  term environments
    doc 0
      freq 4
      pos 15992
      pos 16138
      pos 16176
      pos 16975
    doc 5
      freq 1
      pos 3603
    doc 10
      freq 4
      pos 1718
      pos 3122
      pos 9898
      pos 10727
    doc 12
      freq 4
      pos 465
      pos 1659
      pos 6888
      pos 8082
    doc 13
      freq 1
      pos 5237
    doc 15
      freq 2
      pos 3246
      pos 3291
    doc 16
      freq 1
      pos 444
  term envision
    doc 13
      freq 1
      pos 899
  term eojvezx
    doc 10
      freq 1
      pos 12493
  term epe2olrzpcqj9f23nenk4ufhx1fmzvorgfhuhufbxqa4on
    doc 11
      freq 1
      pos 10412
  term epecqqcge7qshyz8uitlptzdclcwhekh
    doc 10
      freq 1
      pos 6861
  term epgs
    doc 13
      freq 1
      pos 585
  term epsilon
    doc 18
      freq 18
      pos 169
      pos 248
      pos 624
      pos 896
      pos 909
      pos 1032
      pos 1069
      pos 1204
      pos 1229
      pos 1387
      pos 1597
      pos 1715
      pos 1803
      pos 1814
      pos 1865
      pos 1988
      pos 2154
      pos 2197
  term equal
    doc 0
      freq 6
      pos 2481
      pos 3852
      pos 4352
      pos 10956
      pos 11216
      pos 11265
    doc 1
      freq 3
      pos 5138
      pos 7574
      pos 8051
    doc 3
      freq 2
      pos 3298
      pos 4687
    doc 10
      freq 2
      pos 3678
      pos 4844
    doc 12
      freq 2
      pos 2731
      pos 2773
  term equally
    doc 12
      freq 1
      pos 4427
    doc 13
      freq 1
      pos 2631
    doc 15
      freq 1
      pos 664
  term equals
    doc 4
      freq 1
      pos 933
    doc 6
      freq 1
      pos 1274
  term equipment
    doc 2
      freq 1
      pos 3636
    doc 3
      freq 2
      pos 2372
      pos 2458
  term equipment's
    doc 2
      freq 1
      pos 3615
  term equipped
    doc 6
      freq 1
      pos 2586
  term equipping
    doc 6
      freq 1
      pos 2566
  term equivalences
    doc 7
      freq 2
      pos 913
      pos 2377
  term equivalent
    doc 11
      freq 5
      pos 992
      pos 2092
      pos 2140
      pos 2453
      pos 8255
  term equivalents
    doc 14
      freq 1
      pos 639
  term erar1plp0bfioqng4x
    doc 11
      freq 1
      pos 10155
  term erase
    doc 0
      freq 1
      pos 5686
  term eric
    doc 1
      freq 1
      pos 9557
    doc 2
      freq 2
      pos 3587
      pos 6366
    doc 3
      freq 1
      pos 5922
    doc 10
      freq 1
      pos 12109
    doc 11
      freq 1
      pos 9501
  term erik
    doc 2
      freq 1
      pos 5885
    doc 12
      freq 1
      pos 6763
  term eronen
    doc 2
      freq 3
      pos 2309
      pos 2801
      pos 3330
  term erosen
    doc 1
      freq 1
      pos 9570
    doc 3
      freq 1
      pos 5935
  term erroneous
    doc 4
      freq 3
      pos 1861
      pos 3316
      pos 4368
  term error
    doc 0
      freq 5
      pos 3867
      pos 4367
      pos 6898
      pos 11231
      pos 14271
    doc 1
      freq 7
      pos 2340
      pos 2376
      pos 4690
      pos 4958
      pos 5370
      pos 7872
      pos 8825
    doc 3
      freq 4
      pos 244
      pos 3020
      pos 3058
      pos 3086
    doc 4
      freq 44
      pos 183
      pos 690
      pos 695
      pos 716
      pos 761
      pos 800
      pos 990
      pos 1043
      pos 1379
      pos 1405
      pos 1434
      pos 1453
      pos 1459
      pos 1482
      pos 1507
      pos 1521
      pos 1633
      pos 1650
      pos 1835
      pos 1846
      pos 1869
      pos 1925
      pos 1966
      pos 2055
      pos 2086
      pos 2322
      pos 2925
      pos 3342
      pos 3360
      pos 3373
      pos 3467
      pos 4389
      pos 4653
      pos 4657
      pos 4673
      pos 4691
      pos 4699
      pos 4715
      pos 4724
      pos 5140
      pos 5599
      pos 5611
      pos 5716
      pos 5755
    doc 10
      freq 1
      pos 4530
    doc 11
      freq 18
      pos 4267
      pos 4387
      pos 4546
      pos 4572
      pos 4807
      pos 4816
      pos 4838
      pos 5110
      pos 5271
      pos 6527
      pos 6561
      pos 6669
      pos 7203
      pos 7345
      pos 7842
      pos 8118
      pos 8276
      pos 8302
    doc 13
      freq 4
      pos 2089
      pos 2143
      pos 2151
      pos 5065
    doc 16
      freq 2
      pos 602
      pos 608
    skipList 
      level 0
        skipDoc 16
        skipDocFP 850012
        impacts 
          impact 
            freq 2
            norm 99
          impact 
            freq 4
            norm 107
          impact 
            freq 44
            norm 108
        impactsEnd 
  term errors
    doc 0
      freq 4
      pos 7364
      pos 7712
      pos 7728
      pos 15858
    doc 2
      freq 2
      pos 4542
      pos 4597
    doc 3
      freq 2
      pos 3108
      pos 3110
    doc 4
      freq 1
      pos 484
    doc 11
      freq 1
      pos 4187
    doc 13
      freq 2
      pos 2163
      pos 5103
  term erzstr
    doc 15
      freq 1
      pos 4052
  term es
    doc 0
      freq 7
      pos 2632
      pos 2641
      pos 8500
      pos 8520
      pos 8558
      pos 8578
      pos 15887
    doc 12
      freq 1
      pos 3428
  term esc01
    doc 11
      freq 1
      pos 2193
  term esc01.239409asdfakjkn23onasd0
    doc 11
      freq 1
      pos 2217
  term esc02
    doc 11
      freq 2
      pos 2552
      pos 2573
  term escap
    doc 11
      freq 7
      pos 171
      pos 1622
      pos 1776
      pos 1782
      pos 2155
      pos 2412
      pos 2428
  term escaped
    doc 11
      freq 20
      pos 158
      pos 321
      pos 512
      pos 1217
      pos 1789
      pos 2061
      pos 2071
      pos 2163
      pos 2177
      pos 2299
      pos 3477
      pos 3948
      pos 5841
      pos 5857
      pos 5888
      pos 5897
      pos 6276
      pos 8872
      pos 8885
      pos 8901
  term escaping
    doc 11
      freq 3
      pos 154
      pos 2007
      pos 2015
  term escnull
    doc 11
      freq 2
      pos 2356
      pos 2378
  term escrur
    doc 11
      freq 2
      pos 5927
      pos 5953
  term esh
    doc 0
      freq 1
      pos 8585
  term esibov
    doc 12
      freq 1
      pos 7495
    doc 14
      freq 1
      pos 5412
  term esmtp
    doc 16
      freq 2
      pos 1964
      pos 2332
  term esp
    doc 4
      freq 9
      pos 1601
      pos 4050
      pos 4069
      pos 4231
      pos 4342
      pos 5409
      pos 5416
      pos 5941
      pos 5948
    doc 7
      freq 2
      pos 1138
      pos 2727
  term especially
    doc 5
      freq 1
      pos 908
    doc 9
      freq 1
      pos 704
    doc 10
      freq 4
      pos 116
      pos 10071
      pos 10222
      pos 10449
    doc 12
      freq 2
      pos 2754
      pos 4239
    doc 13
      freq 6
      pos 1167
      pos 2455
      pos 2475
      pos 2503
      pos 2641
      pos 2654
    doc 14
      freq 1
      pos 2435
  term espoo
    doc 12
      freq 1
      pos 9458
  term essential
    doc 0
      freq 1
      pos 4921
    doc 5
      freq 1
      pos 3526
    doc 13
      freq 4
      pos 2305
      pos 5235
      pos 5495
      pos 5499
  term est
    doc 11
      freq 1
      pos 6192
  term establish
    doc 0
      freq 1
      pos 13808
    doc 1
      freq 1
      pos 2070
    doc 5
      freq 1
      pos 3302
    doc 17
      freq 1
      pos 1808
  term established
    doc 0
      freq 1
      pos 755
    doc 2
      freq 3
      pos 4025
      pos 5326
      pos 5671
    doc 12
      freq 1
      pos 5845
    doc 13
      freq 1
      pos 796
  term establishing
    doc 1
      freq 1
      pos 171
    doc 9
      freq 1
      pos 607
    doc 10
      freq 2
      pos 1668
      pos 9104
    doc 13
      freq 1
      pos 3290
  term establishment
    doc 5
      freq 1
      pos 3127
    doc 11
      freq 1
      pos 9320
  term estacad
    doc 11
      freq 2
      pos 10
      pos 10530
  term estacado.net
    doc 11
      freq 1
      pos 10534
  term estimated
    doc 5
      freq 1
      pos 2432
  term esuffoqq
    doc 11
      freq 1
      pos 10443
  term et
    doc 1
      freq 33
      pos 198
      pos 421
      pos 829
      pos 1058
      pos 1366
      pos 1859
      pos 2219
      pos 2415
      pos 2689
      pos 3048
      pos 3418
      pos 3603
      pos 3900
      pos 4237
      pos 4631
      pos 5011
      pos 5290
      pos 5682
      pos 6017
      pos 6358
      pos 6753
      pos 7191
      pos 7633
      pos 7883
      pos 8231
      pos 8699
      pos 9014
      pos 9218
      pos 9325
      pos 9395
      pos 9490
      pos 9591
      pos 9924
    doc 3
      freq 24
      pos 161
      pos 326
      pos 573
      pos 753
      pos 1032
      pos 1418
      pos 1771
      pos 2110
      pos 2421
      pos 2816
      pos 3200
      pos 3609
      pos 4003
      pos 4291
      pos 4552
      pos 4733
      pos 4826
      pos 4930
      pos 4995
      pos 5191
      pos 5581
      pos 5782
      pos 5938
      pos 6273
    doc 4
      freq 24
      pos 134
      pos 415
      pos 735
      pos 1004
      pos 1361
      pos 1748
      pos 2070
      pos 2307
      pos 2711
      pos 2957
      pos 3194
      pos 3430
      pos 3620
      pos 3792
      pos 4082
      pos 4492
      pos 4878
      pos 5149
      pos 5394
      pos 5524
      pos 5809
      pos 6028
      pos 6094
      pos 6428
    doc 11
      freq 53
      pos 184
      pos 487
      pos 814
      pos 1040
      pos 1247
      pos 1433
      pos 1567
      pos 1891
      pos 2105
      pos 2285
      pos 2537
      pos 2778
      pos 3046
      pos 3313
      pos 3436
      pos 3681
      pos 3877
      pos 3978
      pos 4164
      pos 4404
      pos 4647
      pos 4885
      pos 5063
      pos 5230
      pos 5387
      pos 5535
      pos 5695
      pos 5827
      pos 6015
      pos 6239
      pos 6475
      pos 6711
      pos 6925
      pos 7135
      pos 7263
      pos 7541
      pos 7775
      pos 8022
      pos 8219
      pos 8451
      pos 8635
      pos 8854
      pos 8953
      pos 9198
      pos 9408
      pos 9715
      pos 9853
      pos 10019
      pos 10209
      pos 10418
      pos 10511
      pos 10614
      pos 10947
    doc 12
      freq 29
      pos 232
      pos 494
      pos 858
      pos 1216
      pos 1553
      pos 1938
      pos 2272
      pos 2643
      pos 3015
      pos 3379
      pos 3808
      pos 4190
      pos 4555
      pos 5006
      pos 5415
      pos 5851
      pos 6241
      pos 6634
      pos 6979
      pos 7226
      pos 7455
      pos 7699
      pos 7879
      pos 8232
      pos 8629
      pos 9041
      pos 9413
      pos 9464
      pos 9797
    doc 13
      freq 23
      pos 117
      pos 347
      pos 751
      pos 1133
      pos 1454
      pos 1813
      pos 2165
      pos 2557
      pos 2928
      pos 3295
      pos 3656
      pos 3957
      pos 4292
      pos 4667
      pos 5012
      pos 5374
      pos 5724
      pos 6003
      pos 6325
      pos 6647
      pos 6937
      pos 7077
      pos 7412
    doc 15
      freq 14
      pos 187
      pos 298
      pos 628
      pos 1018
      pos 1386
      pos 1746
      pos 2141
      pos 2587
      pos 2999
      pos 3400
      pos 3795
      pos 4001
      pos 4064
      pos 4397
  term etc
    doc 1
      freq 1
      pos 3857
    doc 3
      freq 3
      pos 665
      pos 1012
      pos 3510
    doc 12
      freq 1
      pos 2748
    doc 13
      freq 4
      pos 475
      pos 987
      pos 4412
      pos 5276
    doc 15
      freq 3
      pos 1048
      pos 2466
      pos 3107
  term eth
    doc 1
      freq 2
      pos 441
      pos 9097
    doc 8
      freq 4
      pos 654
      pos 657
      pos 1056
      pos 1984
  term ethernet
    doc 1
      freq 3
      pos 117
      pos 1640
      pos 9113
    doc 2
      freq 12
      pos 259
      pos 276
      pos 3192
      pos 3219
      pos 3255
      pos 3682
      pos 3718
      pos 3794
      pos 3961
      pos 3970
      pos 3972
      pos 4006
    doc 3
      freq 128
      pos 35
      pos 101
      pos 108
      pos 125
      pos 137
      pos 158
      pos 171
      pos 200
      pos 205
      pos 210
      pos 336
      pos 344
      pos 348
      pos 375
      pos 411
      pos 450
      pos 485
      pos 517
      pos 533
      pos 536
      pos 550
      pos 568
      pos 583
      pos 630
      pos 633
      pos 638
      pos 696
      pos 723
      pos 724
      pos 746
      pos 763
      pos 814
      pos 819
      pos 935
      pos 942
      pos 980
      pos 1019
      pos 1042
      pos 1108
      pos 1120
      pos 1267
      pos 1280
      pos 1292
      pos 1298
      pos 1312
      pos 1314
      pos 1329
      pos 1333
      pos 1337
      pos 1342
      pos 1351
      pos 1370
      pos 1402
      pos 1428
      pos 1445
      pos 1447
      pos 1471
      pos 1473
      pos 1478
      pos 1502
      pos 1504
      pos 1510
      pos 1542
      pos 1545
      pos 1638
      pos 1640
      pos 1661
      pos 1663
      pos 1695
      pos 1699
      pos 1732
      pos 1781
      pos 1794
      pos 1827
      pos 1838
      pos 1843
      pos 1847
      pos 1872
      pos 1900
      pos 1925
      pos 1928
      pos 2005
      pos 2044
      pos 2120
      pos 2335
      pos 2431
      pos 2484
      pos 2539
      pos 2634
      pos 2670
      pos 2826
      pos 2840
      pos 2915
      pos 2966
      pos 3024
      pos 3084
      pos 3099
      pos 3150
      pos 3210
      pos 3218
      pos 3245
      pos 3248
      pos 3390
      pos 3487
      pos 3527
      pos 3619
      pos 3868
      pos 4013
      pos 4061
      pos 4069
      pos 4088
      pos 4196
      pos 4301
      pos 4539
      pos 4562
      pos 4743
      pos 4836
      pos 4940
      pos 5005
      pos 5032
      pos 5201
      pos 5337
      pos 5350
      pos 5381
      pos 5412
      pos 5591
      pos 5792
      pos 5948
    doc 6
      freq 1
      pos 2541
    doc 8
      freq 3
      pos 651
      pos 656
      pos 2000
  term ethernets
    doc 2
      freq 1
      pos 3949
  term ethertyp
    doc 2
      freq 8
      pos 151
      pos 1852
      pos 1855
      pos 1876
      pos 1894
      pos 1916
      pos 3420
      pos 3436
  term ethertypes
    doc 2
      freq 1
      pos 1893
  term eu7d7ov8hwettdobv3ittmgpwcfjaemmyei3d7syn21yndo2er
    doc 10
      freq 2
      pos 7280
      pos 7370
  term euchner
    doc 5
      freq 1
      pos 4242
  term euro
    doc 11
      freq 1
      pos 1081
  term eurpep60l
    doc 11
      freq 1
      pos 9895
  term evain
    doc 13
      freq 1
      pos 6966
  term evaluat
    doc 10
      freq 1
      pos 10742
  term evaluates
    doc 10
      freq 1
      pos 5665
  term evaluating
    doc 6
      freq 2
      pos 162
      pos 3168
    doc 14
      freq 1
      pos 5496
    doc 16
      freq 1
      pos 916
  term evaluation
    doc 12
      freq 1
      pos 6832
  term even
    doc 0
      freq 3
      pos 5919
      pos 16757
      pos 16769
    doc 1
      freq 2
      pos 1350
      pos 8560
    doc 2
      freq 1
      pos 933
    doc 4
      freq 2
      pos 1971
      pos 5632
    doc 5
      freq 2
      pos 3450
      pos 3606
    doc 6
      freq 2
      pos 1980
      pos 2427
    doc 9
      freq 2
      pos 1356
      pos 1544
    doc 10
      freq 3
      pos 1448
      pos 4718
      pos 9761
    doc 11
      freq 3
      pos 1035
      pos 1121
      pos 3734
    doc 12
      freq 11
      pos 1828
      pos 2707
      pos 3188
      pos 3604
      pos 3931
      pos 4079
      pos 6652
      pos 8202
      pos 8453
      pos 8816
      pos 9177
    doc 13
      freq 4
      pos 3140
      pos 5558
      pos 5940
      pos 6049
    doc 14
      freq 1
      pos 2313
    doc 15
      freq 2
      pos 1940
      pos 2902
    doc 16
      freq 1
      pos 1358
    skipList 
      level 0
        skipDoc 10
        skipDocFP 862034
        impacts 
          impact 
            freq 2
            norm 95
          impact 
            freq 3
            norm 116
        impactsEnd 
  term event
    doc 0
      freq 3
      pos 12868
      pos 13036
      pos 13047
    doc 1
      freq 1
      pos 5201
    doc 7
      freq 1
      pos 242
    doc 9
      freq 1
      pos 1488
    doc 13
      freq 14
      pos 215
      pos 821
      pos 828
      pos 1833
      pos 1859
      pos 2866
      pos 3058
      pos 3065
      pos 3074
      pos 3095
      pos 3098
      pos 3120
      pos 3191
      pos 6914
  term events
    doc 0
      freq 5
      pos 695
      pos 2117
      pos 7198
      pos 7738
      pos 7987
    doc 11
      freq 2
      pos 619
      pos 4191
    doc 13
      freq 2
      pos 391
      pos 2898
    doc 17
      freq 1
      pos 1603
  term every
    doc 1
      freq 1
      pos 3154
    doc 3
      freq 1
      pos 2546
    doc 4
      freq 6
      pos 526
      pos 533
      pos 1432
      pos 1968
      pos 3661
      pos 3827
    doc 9
      freq 5
      pos 1171
      pos 1337
      pos 1343
      pos 1353
      pos 1379
    doc 10
      freq 2
      pos 3970
      pos 11177
    doc 11
      freq 1
      pos 671
    doc 12
      freq 1
      pos 3186
    doc 18
      freq 1
      pos 1142
    skipList 
      level 0
        skipDoc 18
        skipDocFP 863872
        impacts 
          impact 
            freq 5
            norm 95
          impact 
            freq 6
            norm 108
        impactsEnd 
  term everyon
    doc 9
      freq 1
      pos 1626
  term everything
    doc 10
      freq 1
      pos 5257
  term evolution
    doc 2
      freq 1
      pos 3942
  term exact
    doc 10
      freq 6
      pos 364
      pos 4893
      pos 6166
      pos 9770
      pos 9910
      pos 12179
    doc 11
      freq 2
      pos 545
      pos 9731
    doc 18
      freq 1
      pos 1538
  term exactly
    doc 1
      freq 4
      pos 2214
      pos 4452
      pos 5867
      pos 6480
    doc 3
      freq 1
      pos 822
    doc 4
      freq 1
      pos 5615
    doc 9
      freq 1
      pos 1003
    doc 10
      freq 7
      pos 2302
      pos 2776
      pos 2928
      pos 5057
      pos 5213
      pos 8945
      pos 10655
    doc 11
      freq 1
      pos 3595
    doc 13
      freq 1
      pos 5170
  term examin
    doc 3
      freq 1
      pos 3363
    doc 12
      freq 1
      pos 8095
  term examination
    doc 6
      freq 1
      pos 2824
  term examining
    doc 1
      freq 1
      pos 1452
  term exampl
    doc 0
      freq 1
      pos 16765
    doc 1
      freq 7
      pos 1380
      pos 1565
      pos 4144
      pos 4476
      pos 4493
      pos 7500
      pos 8593
    doc 2
      freq 2
      pos 1751
      pos 1995
    doc 3
      freq 5
      pos 2387
      pos 3490
      pos 4221
      pos 5484
      pos 5525
    doc 4
      freq 7
      pos 1552
      pos 1594
      pos 1958
      pos 2018
      pos 2465
      pos 3471
      pos 5593
    doc 5
      freq 2
      pos 3189
      pos 3312
    doc 6
      freq 4
      pos 622
      pos 871
      pos 2084
      pos 2632
    doc 9
      freq 2
      pos 612
      pos 922
    doc 10
      freq 15
      pos 564
      pos 740
      pos 768
      pos 2755
      pos 2873
      pos 3107
      pos 3465
      pos 3873
      pos 6118
      pos 6938
      pos 8841
      pos 10939
      pos 11772
      pos 12160
      pos 12216
    doc 11
      freq 6
      pos 654
      pos 775
      pos 1126
      pos 6334
      pos 9702
      pos 9755
    doc 12
      freq 11
      pos 1532
      pos 2026
      pos 2147
      pos 2609
      pos 2824
      pos 3418
      pos 3534
      pos 5300
      pos 5316
      pos 8367
      pos 8388
    doc 13
      freq 13
      pos 816
      pos 1301
      pos 3152
      pos 3212
      pos 3241
      pos 3353
      pos 3388
      pos 3581
      pos 3915
      pos 5767
      pos 6176
      pos 6462
      pos 6721
    doc 14
      freq 20
      pos 2960
      pos 3228
      pos 3266
      pos 3550
      pos 3848
      pos 4152
      pos 4160
      pos 4230
      pos 4295
      pos 4417
      pos 4511
      pos 4593
      pos 4880
      pos 4971
      pos 4987
      pos 5010
      pos 5026
      pos 5134
      pos 5144
      pos 5162
    doc 15
      freq 15
      pos 1047
      pos 1185
      pos 1267
      pos 1351
      pos 1441
      pos 1543
      pos 1905
      pos 2026
      pos 2053
      pos 2195
      pos 2537
      pos 2625
      pos 3068
      pos 3354
      pos 3745
    doc 16
      freq 10
      pos 1345
      pos 1741
      pos 1745
      pos 1862
      pos 1866
      pos 2120
      pos 2124
      pos 2257
      pos 2261
      pos 2285
    doc 17
      freq 2
      pos 1130
      pos 1820
    doc 18
      freq 4
      pos 970
      pos 1012
      pos 1117
      pos 1135
    skipList 
      level 0
        skipDoc 9
        skipDocFP 865572
        impacts 
          impact 
            freq 2
            norm 95
          impact 
            freq 4
            norm 101
          impact 
            freq 5
            norm 107
          impact 
            freq 7
            norm 108
        impactsEnd 
        skipDoc 17
        skipDocFP 866203
        impacts 
          impact 
            freq 2
            norm 98
          impact 
            freq 10
            norm 99
          impact 
            freq 15
            norm 104
          impact 
            freq 20
            norm 107
        impactsEnd 
  term exampld.com
    doc 18
      freq 1
      pos 1008
  term exampldd.com
    doc 18
      freq 3
      pos 1064
      pos 1120
      pos 1131
  term example.com
    doc 10
      freq 9
      pos 1805
      pos 1812
      pos 1934
      pos 2982
      pos 2985
      pos 7839
      pos 10488
      pos 10503
      pos 10627
    doc 11
      freq 156
      pos 1466
      pos 1526
      pos 1928
      pos 1937
      pos 1963
      pos 1971
      pos 2036
      pos 2205
      pos 2365
      pos 2370
      pos 2388
      pos 2395
      pos 2401
      pos 2493
      pos 2563
      pos 2568
      pos 2594
      pos 2599
      pos 2603
      pos 2676
      pos 2681
      pos 2685
      pos 2796
      pos 2814
      pos 2924
      pos 2930
      pos 2936
      pos 2942
      pos 2948
      pos 2954
      pos 2960
      pos 2966
      pos 2972
      pos 2978
      pos 2984
      pos 2990
      pos 2996
      pos 3002
      pos 3008
      pos 3014
      pos 3020
      pos 3026
      pos 3032
      pos 3038
      pos 3044
      pos 3064
      pos 3070
      pos 3076
      pos 3082
      pos 3088
      pos 3094
      pos 3100
      pos 3106
      pos 3112
      pos 3118
      pos 3124
      pos 3130
      pos 3335
      pos 3338
      pos 3365
      pos 3370
      pos 3512
      pos 3517
      pos 3615
      pos 3620
      pos 3623
      pos 3643
      pos 3651
      pos 3659
      pos 3667
      pos 3675
      pos 3819
      pos 4025
      pos 4043
      pos 4148
      pos 4162
      pos 4273
      pos 4278
      pos 4449
      pos 4457
      pos 4478
      pos 4665
      pos 4673
      pos 4910
      pos 4915
      pos 4918
      pos 4940
      pos 5031
      pos 5039
      pos 5145
      pos 5153
      pos 5161
      pos 5314
      pos 5319
      pos 5454
      pos 5460
      pos 5620
      pos 5628
      pos 5637
      pos 5646
      pos 5787
      pos 5798
      pos 5804
      pos 5808
      pos 5930
      pos 5938
      pos 6155
      pos 6160
      pos 6350
      pos 6353
      pos 6376
      pos 6444
      pos 6455
      pos 6616
      pos 6692
      pos 6765
      pos 6770
      pos 6857
      pos 6862
      pos 6986
      pos 7000
      pos 7102
      pos 7107
      pos 7209
      pos 7383
      pos 7403
      pos 7514
      pos 7534
      pos 7735
      pos 7740
      pos 7848
      pos 7857
      pos 8044
      pos 8047
      pos 8157
      pos 8162
      pos 8317
      pos 8330
      pos 8494
      pos 8512
      pos 8603
      pos 8608
      pos 8625
      pos 8742
      pos 8747
      pos 8832
      pos 8837
      pos 8920
      pos 8923
      pos 8941
      pos 8946
      pos 9066
      pos 9071
      pos 9246
      pos 9263
      pos 9266
    doc 12
      freq 4
      pos 2338
      pos 2831
      pos 2910
      pos 5973
    doc 14
      freq 37
      pos 2898
      pos 3203
      pos 3217
      pos 3287
      pos 3572
      pos 3809
      pos 3823
      pos 3877
      pos 4116
      pos 4129
      pos 4192
      pos 4215
      pos 4259
      pos 4280
      pos 4384
      pos 4391
      pos 4402
      pos 4476
      pos 4496
      pos 4557
      pos 4578
      pos 4856
      pos 4869
      pos 4872
      pos 4948
      pos 4956
      pos 5008
      pos 5024
      pos 5025
      pos 5055
      pos 5119
      pos 5126
      pos 5143
      pos 5161
      pos 5263
      pos 5270
      pos 5273
    doc 15
      freq 3
      pos 1357
      pos 1370
      pos 1423
    doc 18
      freq 6
      pos 982
      pos 998
      pos 1451
      pos 1521
      pos 1526
      pos 1553
  term example.edu
    doc 11
      freq 4
      pos 4030
      pos 4153
      pos 6991
      pos 8499
  term example.net
    doc 11
      freq 46
      pos 2046
      pos 2198
      pos 2210
      pos 2227
      pos 2237
      pos 2847
      pos 3160
      pos 3373
      pos 3503
      pos 4281
      pos 4460
      pos 4676
      pos 4696
      pos 5042
      pos 5147
      pos 5164
      pos 5176
      pos 5322
      pos 5344
      pos 5467
      pos 5492
      pos 5631
      pos 5652
      pos 5941
      pos 5950
      pos 6163
      pos 6196
      pos 6773
      pos 6865
      pos 7386
      pos 7517
      pos 7743
      pos 7854
      pos 7860
      pos 8130
      pos 8165
      pos 8168
      pos 8180
      pos 8325
      pos 8333
      pos 8611
      pos 8759
      pos 8849
      pos 9075
      pos 9078
      pos 9271
    doc 16
      freq 1
      pos 2009
  term example.org
    doc 10
      freq 2
      pos 1818
      pos 10637
    doc 11
      freq 11
      pos 3520
      pos 3773
      pos 3816
      pos 4301
      pos 6436
      pos 6462
      pos 6598
      pos 6623
      pos 6675
      pos 6699
      pos 7110
    doc 16
      freq 7
      pos 1952
      pos 1978
      pos 1994
      pos 2320
      pos 2346
      pos 2362
      pos 2377
  term example53
    doc 11
      freq 1
      pos 4695
  term examples
    doc 3
      freq 2
      pos 4018
      pos 5443
    doc 6
      freq 1
      pos 2240
    doc 10
      freq 10
      pos 232
      pos 367
      pos 5556
      pos 5943
      pos 5945
      pos 6000
      pos 6064
      pos 6156
      pos 12182
      pos 12205
    doc 11
      freq 9
      pos 79
      pos 788
      pos 881
      pos 1000
      pos 1093
      pos 3747
      pos 3764
      pos 9316
      pos 9520
    doc 13
      freq 2
      pos 2780
      pos 5497
    doc 14
      freq 11
      pos 228
      pos 231
      pos 240
      pos 249
      pos 257
      pos 2885
      pos 2889
      pos 2953
      pos 4145
      pos 4874
      pos 5128
    doc 16
      freq 3
      pos 1596
      pos 1696
      pos 1714
  term exceed
    doc 0
      freq 1
      pos 7530
    doc 3
      freq 1
      pos 4250
    doc 4
      freq 1
      pos 1462
    doc 14
      freq 2
      pos 527
      pos 1374
    doc 16
      freq 1
      pos 1334
  term exceeded
    doc 4
      freq 10
      pos 199
      pos 778
      pos 1942
      pos 3001
      pos 3082
      pos 3089
      pos 3147
      pos 3175
      pos 3214
      pos 5684
    doc 14
      freq 1
      pos 1153
  term exceeding
    doc 4
      freq 4
      pos 2143
      pos 2809
      pos 3054
      pos 3290
  term exceeds
    doc 0
      freq 1
      pos 14023
    doc 3
      freq 2
      pos 2893
      pos 4272
    doc 16
      freq 1
      pos 1402
  term excellent
    doc 3
      freq 1
      pos 5721
    doc 13
      freq 1
      pos 6980
  term except
    doc 0
      freq 1
      pos 17247
    doc 1
      freq 2
      pos 4227
      pos 9628
    doc 2
      freq 1
      pos 6425
    doc 3
      freq 2
      pos 5130
      pos 5977
    doc 4
      freq 1
      pos 6132
    doc 5
      freq 1
      pos 4462
    doc 6
      freq 1
      pos 3262
    doc 7
      freq 1
      pos 2967
    doc 8
      freq 1
      pos 2184
    doc 9
      freq 1
      pos 1829
    doc 10
      freq 1
      pos 13490
    doc 11
      freq 1
      pos 10651
    doc 12
      freq 5
      pos 3762
      pos 5282
      pos 6011
      pos 6145
      pos 9501
    doc 13
      freq 1
      pos 7116
    doc 14
      freq 1
      pos 5582
    doc 15
      freq 1
      pos 4101
    doc 16
      freq 2
      pos 1533
      pos 2712
    doc 17
      freq 1
      pos 2436
    doc 18
      freq 1
      pos 2224
    skipList 
      level 0
        skipDoc 7
        skipDocFP 874925
        impacts 
          impact 
            freq 1
            norm 100
          impact 
            freq 2
            norm 107
        impactsEnd 
        skipDoc 15
        skipDocFP 875260
        impacts 
          impact 
            freq 1
            norm 95
          impact 
            freq 5
            norm 113
        impactsEnd 
  term exception
    doc 4
      freq 2
      pos 2912
      pos 4395
    doc 12
      freq 2
      pos 3690
      pos 3788
  term exceptions
    doc 4
      freq 3
      pos 1673
      pos 1738
      pos 1773
    doc 10
      freq 1
      pos 2946
  term excessiv
    doc 6
      freq 1
      pos 1000
  term exchang
    doc 0
      freq 1
      pos 16895
    doc 2
      freq 4
      pos 2531
      pos 2587
      pos 2628
      pos 2665
    doc 3
      freq 1
      pos 4418
    doc 5
      freq 23
      pos 773
      pos 802
      pos 839
      pos 845
      pos 892
      pos 1027
      pos 2161
      pos 2980
      pos 3032
      pos 3040
      pos 3063
      pos 3085
      pos 3110
      pos 3130
      pos 3147
      pos 3165
      pos 3273
      pos 3395
      pos 3440
      pos 3503
      pos 3515
      pos 3542
      pos 3642
    doc 7
      freq 4
      pos 731
      pos 999
      pos 2068
      pos 2487
    doc 10
      freq 2
      pos 10649
      pos 10975
    doc 12
      freq 1
      pos 4594
    doc 13
      freq 4
      pos 299
      pos 2491
      pos 5043
      pos 5055
    skipList 
      level 0
        skipDoc 13
        skipDocFP 876502
        impacts 
          impact 
            freq 4
            norm 100
          impact 
            freq 23
            norm 104
        impactsEnd 
  term exchanged
    doc 5
      freq 5
      pos 868
      pos 3294
      pos 3366
      pos 3390
      pos 3556
  term exchanges
    doc 4
      freq 2
      pos 4032
      pos 4057
    doc 5
      freq 2
      pos 3419
      pos 3421
    doc 13
      freq 1
      pos 2418
  term exchanging
    doc 13
      freq 1
      pos 1325
  term exclud
    doc 0
      freq 2
      pos 1178
      pos 15873
  term excluding
    doc 0
      freq 3
      pos 3820
      pos 4320
      pos 11184
    doc 1
      freq 1
      pos 6155
    doc 14
      freq 1
      pos 2921
  term exclusiv
    doc 7
      freq 1
      pos 1346
    doc 13
      freq 1
      pos 4616
  term exclusively
    doc 14
      freq 1
      pos 491
  term excomm
    doc 2
      freq 1
      pos 454
  term excursions
    doc 6
      freq 3
      pos 1569
      pos 2441
      pos 2721
  term execut
    doc 1
      freq 1
      pos 7068
  term executed
    doc 5
      freq 1
      pos 2860
  term executiv
    doc 2
      freq 4
      pos 372
      pos 452
      pos 1018
      pos 6300
  term exercis
    doc 6
      freq 2
      pos 159
      pos 1099
    doc 11
      freq 4
      pos 89
      pos 595
      pos 7010
      pos 7157
  term exercises
    doc 11
      freq 3
      pos 1588
      pos 2011
      pos 3575
  term exhaust
    doc 13
      freq 2
      pos 6434
      pos 6449
  term exhibits
    doc 10
      freq 1
      pos 9547
  term exist
    doc 7
      freq 1
      pos 1749
    doc 10
      freq 2
      pos 3133
      pos 7965
    doc 14
      freq 3
      pos 454
      pos 1823
      pos 2632
    doc 16
      freq 1
      pos 210
    doc 18
      freq 3
      pos 203
      pos 614
      pos 835
  term existenc
    doc 0
      freq 4
      pos 3891
      pos 4391
      pos 5656
      pos 10116
    doc 14
      freq 5
      pos 107
      pos 173
      pos 1202
      pos 1765
      pos 2603
    doc 17
      freq 1
      pos 1428
    doc 18
      freq 5
      pos 750
      pos 919
      pos 994
      pos 1004
      pos 1049
  term existencestat
    doc 0
      freq 1
      pos 11423
  term existent
    doc 14
      freq 1
      pos 330
    doc 18
      freq 2
      pos 937
      pos 1367
  term existing
    doc 3
      freq 1
      pos 128
    doc 4
      freq 1
      pos 947
    doc 5
      freq 1
      pos 3829
    doc 7
      freq 1
      pos 580
    doc 10
      freq 6
      pos 92
      pos 410
      pos 2505
      pos 4321
      pos 4753
      pos 10847
    doc 11
      freq 1
      pos 1387
    doc 12
      freq 1
      pos 4324
    doc 13
      freq 4
      pos 1079
      pos 1543
      pos 3690
      pos 4739
    doc 16
      freq 1
      pos 141
    doc 18
      freq 7
      pos 711
      pos 779
      pos 792
      pos 866
      pos 1061
      pos 1097
      pos 1275
    skipList 
      level 0
        skipDoc 13
        skipDocFP 879715
        impacts 
          impact 
            freq 1
            norm 100
          impact 
            freq 4
            norm 109
          impact 
            freq 6
            norm 116
        impactsEnd 
  term exists
    doc 0
      freq 3
      pos 5443
      pos 6309
      pos 7783
    doc 3
      freq 1
      pos 5209
    doc 5
      freq 2
      pos 398
      pos 453
    doc 12
      freq 4
      pos 3357
      pos 3429
      pos 3438
      pos 5233
    doc 14
      freq 1
      pos 1798
    doc 16
      freq 1
      pos 336
    doc 18
      freq 3
      pos 1122
      pos 1542
      pos 1959
  term exp
    doc 3
      freq 2
      pos 3818
      pos 3843
  term expand
    doc 13
      freq 1
      pos 481
  term expanded
    doc 4
      freq 1
      pos 965
  term expansion
    doc 4
      freq 5
      pos 797
      pos 826
      pos 890
      pos 5137
      pos 5166
  term expansions
    doc 11
      freq 3
      pos 1677
      pos 2138
      pos 2182
  term expect
    doc 10
      freq 1
      pos 11166
    doc 13
      freq 1
      pos 952
  term expected
    doc 4
      freq 2
      pos 852
      pos 2004
    doc 5
      freq 1
      pos 1450
    doc 6
      freq 2
      pos 576
      pos 2861
    doc 7
      freq 1
      pos 679
    doc 9
      freq 1
      pos 1407
    doc 10
      freq 3
      pos 10069
      pos 11113
      pos 11361
    doc 12
      freq 1
      pos 6744
    doc 13
      freq 1
      pos 5088
    doc 18
      freq 1
      pos 704
    skipList 
      level 0
        skipDoc 13
        skipDocFP 881461
        impacts 
          impact 
            freq 1
            norm 95
          impact 
            freq 2
            norm 101
          impact 
            freq 3
            norm 116
        impactsEnd 
  term expecting
    doc 1
      freq 1
      pos 7554
  term expects
    doc 10
      freq 1
      pos 10640
  term experienc
    doc 2
      freq 2
      pos 1958
      pos 2040
    doc 6
      freq 1
      pos 2684
    doc 10
      freq 1
      pos 10924
    doc 12
      freq 3
      pos 141
      pos 542
      pos 8044
    doc 15
      freq 1
      pos 3658
  term experiment
    doc 7
      freq 10
      pos 28
      pos 77
      pos 318
      pos 330
      pos 1240
      pos 1450
      pos 1485
      pos 1522
      pos 1542
      pos 1767
  term experimental
    doc 4
      freq 1
      pos 4829
    doc 7
      freq 2
      pos 698
      pos 1994
    doc 12
      freq 1
      pos 7670
    doc 14
      freq 25
      pos 12
      pos 31
      pos 212
      pos 555
      pos 839
      pos 1216
      pos 1545
      pos 1866
      pos 2156
      pos 2547
      pos 2901
      pos 3254
      pos 3538
      pos 3836
      pos 4132
      pos 4218
      pos 4283
      pos 4405
      pos 4499
      pos 4581
      pos 4959
      pos 5187
      pos 5453
      pos 5546
      pos 5879
    doc 16
      freq 1
      pos 1653
  term experimentation
    doc 4
      freq 10
      pos 790
      pos 793
      pos 819
      pos 822
      pos 842
      pos 5130
      pos 5133
      pos 5144
      pos 5147
      pos 5726
    doc 6
      freq 1
      pos 750
  term experiments
    doc 4
      freq 1
      pos 856
  term expert
    doc 5
      freq 2
      pos 3791
      pos 4007
    doc 8
      freq 12
      pos 121
      pos 252
      pos 377
      pos 391
      pos 398
      pos 442
      pos 463
      pos 526
      pos 856
      pos 1182
      pos 1363
      pos 1552
  term expertis
    doc 2
      freq 1
      pos 3595
    doc 12
      freq 1
      pos 6939
  term expir
    doc 17
      freq 1
      pos 1601
  term expiration
    doc 0
      freq 1
      pos 2176
    doc 11
      freq 1
      pos 4852
    doc 12
      freq 1
      pos 4847
  term expired
    doc 2
      freq 2
      pos 4656
      pos 4825
    doc 10
      freq 2
      pos 4080
      pos 4139
    doc 12
      freq 1
      pos 2961
  term expires
    doc 11
      freq 4
      pos 4775
      pos 4784
      pos 4930
      pos 4941
    doc 12
      freq 2
      pos 2989
      pos 4830
  term expiry
    doc 11
      freq 1
      pos 4834
  term explained
    doc 1
      freq 1
      pos 444
    doc 13
      freq 1
      pos 1092
  term explaining
    doc 16
      freq 1
      pos 2147
  term explanation
    doc 1
      freq 1
      pos 2578
  term explicit
    doc 0
      freq 2
      pos 10237
      pos 10310
    doc 11
      freq 1
      pos 9215
    doc 12
      freq 3
      pos 2821
      pos 6001
      pos 6439
  term explicitly
    doc 2
      freq 1
      pos 3781
    doc 9
      freq 1
      pos 1250
    doc 11
      freq 1
      pos 6124
    doc 12
      freq 5
      pos 2376
      pos 2937
      pos 3092
      pos 4548
      pos 4746
    doc 14
      freq 1
      pos 2265
    doc 17
      freq 2
      pos 91
      pos 237
  term explicittext
    doc 17
      freq 5
      pos 1107
      pos 1193
      pos 1204
      pos 1221
      pos 1252
  term exploit
    doc 10
      freq 1
      pos 3228
  term explored
    doc 10
      freq 1
      pos 9932
    doc 12
      freq 1
      pos 4356
  term exploring
    doc 11
      freq 2
      pos 686
      pos 4193
  term exports
    doc 17
      freq 1
      pos 2197
  term expos
    doc 18
      freq 1
      pos 545
  term exposed
    doc 2
      freq 1
      pos 2091
  term exposur
    doc 9
      freq 1
      pos 1045
    doc 14
      freq 2
      pos 291
      pos 5334
    doc 18
      freq 1
      pos 435
  term express
    doc 0
      freq 1
      pos 17298
    doc 1
      freq 1
      pos 9679
    doc 2
      freq 1
      pos 6476
    doc 3
      freq 1
      pos 6028
    doc 4
      freq 1
      pos 6183
    doc 5
      freq 1
      pos 4513
    doc 6
      freq 1
      pos 3313
    doc 7
      freq 1
      pos 3018
    doc 8
      freq 1
      pos 2235
    doc 9
      freq 1
      pos 1880
    doc 10
      freq 3
      pos 468
      pos 909
      pos 13541
    doc 11
      freq 1
      pos 10702
    doc 12
      freq 1
      pos 9552
    doc 13
      freq 1
      pos 7167
    doc 14
      freq 1
      pos 5633
    doc 15
      freq 1
      pos 4152
    doc 16
      freq 1
      pos 2763
    doc 17
      freq 1
      pos 2487
    doc 18
      freq 1
      pos 2275
    skipList 
      level 0
        skipDoc 7
        skipDocFP 885834
        impacts 
          impact 
            freq 1
            norm 100
        impactsEnd 
        skipDoc 15
        skipDocFP 886139
        impacts 
          impact 
            freq 1
            norm 95
          impact 
            freq 3
            norm 116
        impactsEnd 
  term expressed
    doc 0
      freq 2
      pos 14436
      pos 14602
    doc 6
      freq 2
      pos 1334
      pos 2222
    doc 13
      freq 1
      pos 603
    doc 14
      freq 1
      pos 2935
  term expression
    doc 14
      freq 1
      pos 582
  term expunged
    doc 16
      freq 1
      pos 2469
  term extend
    doc 2
      freq 1
      pos 6136
    doc 13
      freq 2
      pos 1990
      pos 2134
  term extended
    doc 0
      freq 2
      pos 6229
      pos 9158
    doc 1
      freq 2
      pos 1821
      pos 2076
    doc 2
      freq 1
      pos 1740
    doc 6
      freq 1
      pos 3054
    doc 7
      freq 3
      pos 963
      pos 1836
      pos 2407
    doc 15
      freq 1
      pos 3322
    doc 16
      freq 6
      pos 418
      pos 717
      pos 827
      pos 999
      pos 1456
      pos 1466
  term extending
    doc 2
      freq 1
      pos 4703
    doc 7
      freq 1
      pos 2697
    doc 13
      freq 1
      pos 3841
  term extends
    doc 10
      freq 1
      pos 1675
    doc 15
      freq 2
      pos 2236
      pos 2331
    doc 16
      freq 2
      pos 97
      pos 229
  term extensibility
    doc 13
      freq 1
      pos 1936
  term extensibl
    doc 2
      freq 8
      pos 287
      pos 2315
      pos 2806
      pos 2961
      pos 3150
      pos 3275
      pos 3291
      pos 3340
    doc 13
      freq 1
      pos 1929
  term extension
    doc 2
      freq 1
      pos 250
    doc 4
      freq 5
      pos 547
      pos 1567
      pos 1602
      pos 3394
      pos 3495
    doc 5
      freq 2
      pos 295
      pos 2566
    doc 7
      freq 5
      pos 856
      pos 2133
      pos 2142
      pos 2266
      pos 2855
    doc 10
      freq 2
      pos 4839
      pos 4848
    doc 11
      freq 4
      pos 1836
      pos 3578
      pos 7688
      pos 7701
    doc 12
      freq 2
      pos 7089
      pos 9323
    doc 16
      freq 32
      pos 25
      pos 89
      pos 132
      pos 171
      pos 178
      pos 228
      pos 284
      pos 291
      pos 309
      pos 516
      pos 537
      pos 558
      pos 912
      pos 1040
      pos 1085
      pos 1189
      pos 1317
      pos 1572
      pos 1602
      pos 1691
      pos 1859
      pos 1871
      pos 1916
      pos 2117
      pos 2129
      pos 2254
      pos 2291
      pos 2516
      pos 2554
      pos 2600
      pos 2645
      pos 2685
    doc 17
      freq 33
      pos 22
      pos 89
      pos 159
      pos 217
      pos 234
      pos 297
      pos 421
      pos 423
      pos 440
      pos 458
      pos 501
      pos 518
      pos 549
      pos 599
      pos 618
      pos 625
      pos 636
      pos 658
      pos 720
      pos 776
      pos 784
      pos 818
      pos 979
      pos 1056
      pos 1402
      pos 1851
      pos 1901
      pos 1948
      pos 1962
      pos 2116
      pos 2154
      pos 2323
      pos 2409
    skipList 
      level 0
        skipDoc 16
        skipDocFP 888357
        impacts 
          impact 
            freq 32
            norm 99
        impactsEnd 
  term extensionheader
    doc 11
      freq 1
      pos 1994
  term extensions
    doc 0
      freq 2
      pos 1768
      pos 1812
    doc 1
      freq 4
      pos 177
      pos 246
      pos 2268
      pos 7935
    doc 2
      freq 10
      pos 1402
      pos 1568
      pos 2175
      pos 2190
      pos 3011
      pos 3098
      pos 3405
      pos 4712
      pos 5976
      pos 6286
    doc 5
      freq 7
      pos 500
      pos 797
      pos 2570
      pos 2577
      pos 2765
      pos 3739
      pos 3746
    doc 7
      freq 8
      pos 709
      pos 976
      pos 2033
      pos 2077
      pos 2428
      pos 2503
      pos 2511
      pos 2521
    doc 8
      freq 9
      pos 291
      pos 563
      pos 598
      pos 894
      pos 976
      pos 1219
      pos 1270
      pos 1400
      pos 1465
    doc 10
      freq 1
      pos 13295
    doc 12
      freq 2
      pos 7130
      pos 7270
    doc 13
      freq 1
      pos 2379
    doc 14
      freq 1
      pos 5446
    doc 16
      freq 4
      pos 1445
      pos 1471
      pos 2578
      pos 2628
    doc 17
      freq 1
      pos 452
    doc 18
      freq 2
      pos 2098
      pos 2121
    skipList 
      level 0
        skipDoc 12
        skipDocFP 890064
        impacts 
          impact 
            freq 9
            norm 97
          impact 
            freq 10
            norm 108
        impactsEnd 
  term extensiv
    doc 0
      freq 1
      pos 16400
    doc 4
      freq 1
      pos 5509
    doc 12
      freq 3
      pos 525
      pos 2884
      pos 6827
  term extensively
    doc 12
      freq 1
      pos 4677
  term extent
    doc 0
      freq 1
      pos 17372
    doc 1
      freq 1
      pos 9753
    doc 2
      freq 1
      pos 6550
    doc 3
      freq 1
      pos 6102
    doc 4
      freq 1
      pos 6257
    doc 5
      freq 1
      pos 4587
    doc 6
      freq 1
      pos 3387
    doc 7
      freq 1
      pos 3092
    doc 8
      freq 1
      pos 2309
    doc 9
      freq 1
      pos 1954
    doc 10
      freq 1
      pos 13615
    doc 11
      freq 1
      pos 10776
    doc 12
      freq 1
      pos 9626
    doc 13
      freq 3
      pos 5057
      pos 5093
      pos 7241
    doc 14
      freq 1
      pos 5707
    doc 15
      freq 1
      pos 4226
    doc 16
      freq 1
      pos 2837
    doc 17
      freq 1
      pos 2561
    doc 18
      freq 1
      pos 2349
    skipList 
      level 0
        skipDoc 7
        skipDocFP 891598
        impacts 
          impact 
            freq 1
            norm 100
        impactsEnd 
        skipDoc 15
        skipDocFP 891903
        impacts 
          impact 
            freq 1
            norm 95
          impact 
            freq 3
            norm 109
        impactsEnd 
  term external
    doc 0
      freq 4
      pos 1837
      pos 1850
      pos 10521
      pos 11547
    doc 1
      freq 1
      pos 8143
    doc 9
      freq 1
      pos 604
  term externaldomain
    doc 0
      freq 1
      pos 5817
  term extra
    doc 1
      freq 1
      pos 7065
    doc 11
      freq 10
      pos 205
      pos 3203
      pos 3230
      pos 3243
      pos 3283
      pos 4611
      pos 5589
      pos 5607
      pos 5755
      pos 5773
    doc 15
      freq 1
      pos 1728
  term extract
    doc 10
      freq 2
      pos 2345
      pos 2392
    doc 17
      freq 1
      pos 1165
  term extractdsp
    doc 0
      freq 3
      pos 10241
      pos 10392
      pos 10732
  term extracted
    doc 0
      freq 3
      pos 10438
      pos 10646
      pos 10753
    doc 3
      freq 1
      pos 466
    doc 4
      freq 1
      pos 1495
    doc 10
      freq 1
      pos 12337
  term extractid
    doc 0
      freq 2
      pos 10239
      pos 10322
  term extraction
    doc 0
      freq 4
      pos 10356
      pos 10411
      pos 10649
      pos 10694
  term extracts
    doc 0
      freq 2
      pos 10338
      pos 10413
  term extraneous
    doc 11
      freq 2
      pos 249
      pos 4221
  term extrem
    doc 11
      freq 1
      pos 2810
  term extremely
    doc 12
      freq 1
      pos 1655
  term ey1det
    doc 10
      freq 1
      pos 12725
  term eyrapfz
    doc 10
      freq 1
      pos 12799
  term ezqgs4vqnga30c5r3ksi8odevsvtff6v6vicbsmd8j
    doc 10
      freq 1
      pos 12504
  term f
    doc 0
      freq 3
      pos 10371
      pos 16984
      pos 16996
    doc 2
      freq 3
      pos 2254
      pos 2302
      pos 2306
    doc 4
      freq 4
      pos 1820
      pos 2041
      pos 4379
      pos 5441
    doc 5
      freq 15
      pos 1220
      pos 1236
      pos 1274
      pos 1318
      pos 1344
      pos 1909
      pos 1911
      pos 1915
      pos 1918
      pos 1924
      pos 2079
      pos 2082
      pos 2098
      pos 2100
      pos 4168
    doc 10
      freq 2
      pos 12741
      pos 12815
    doc 11
      freq 3
      pos 2840
      pos 10058
      pos 10250
    doc 12
      freq 3
      pos 5345
      pos 7388
      pos 7529
  term f00
    doc 12
      freq 1
      pos 5332
  term f232jadfj23
    doc 11
      freq 1
      pos 2570
  term f308dql
    doc 11
      freq 1
      pos 10460
  term f7togs5wbfldupdkxu1txs7dnkn1mgfumfwgnmhb8ajh0omt08vc23jtj1o0a9sn
    doc 10
      freq 1
      pos 12517
  term f9qcmmvqv
    doc 10
      freq 1
      pos 12770
  term faced
    doc 1
      freq 1
      pos 8215
    doc 12
      freq 1
      pos 7960
    doc 15
      freq 1
      pos 1974
  term facilitat
    doc 12
      freq 2
      pos 1966
      pos 8004
  term facilitating
    doc 13
      freq 1
      pos 658
  term facilities
    doc 3
      freq 1
      pos 3238
    doc 5
      freq 1
      pos 3089
    doc 6
      freq 1
      pos 2548
    doc 12
      freq 1
      pos 7004
    doc 14
      freq 1
      pos 5369
  term facing
    doc 8
      freq 2
      pos 1616
      pos 1625
  term fact
    doc 1
      freq 1
      pos 1427
    doc 5
      freq 1
      pos 3523
    doc 7
      freq 2
      pos 641
      pos 1270
    doc 10
      freq 1
      pos 573
    doc 11
      freq 1
      pos 7348
    doc 12
      freq 2
      pos 1732
      pos 6014
  term facto
    doc 10
      freq 1
      pos 10928
  term factor
    doc 6
      freq 9
      pos 1153
      pos 1163
      pos 1166
      pos 1467
      pos 1574
      pos 1600
      pos 2159
      pos 2178
      pos 2692
    doc 10
      freq 1
      pos 11382
    doc 17
      freq 1
      pos 1570
  term factors
    doc 4
      freq 1
      pos 4707
  term fail
    doc 3
      freq 1
      pos 1737
    doc 10
      freq 1
      pos 3239
    doc 11
      freq 4
      pos 7585
      pos 7809
      pos 7917
      pos 8403
    doc 12
      freq 1
      pos 3736
    doc 13
      freq 1
      pos 4001
    doc 16
      freq 1
      pos 1307
  term failed
    doc 0
      freq 5
      pos 7984
      pos 8202
      pos 8975
      pos 9006
      pos 12650
    doc 4
      freq 3
      pos 2194
      pos 5110
      pos 5698
    doc 16
      freq 2
      pos 2264
      pos 2466
  term failing
    doc 12
      freq 1
      pos 8574
    doc 17
      freq 1
      pos 1802
  term fails
    doc 0
      freq 1
      pos 5329
    doc 4
      freq 1
      pos 1863
    doc 9
      freq 1
      pos 1290
    doc 15
      freq 2
      pos 2835
      pos 2841
    doc 16
      freq 3
      pos 1225
      pos 1233
      pos 1259
  term failur
    doc 1
      freq 4
      pos 2727
      pos 4192
      pos 5158
      pos 5193
    doc 3
      freq 2
      pos 1791
      pos 1869
    doc 4
      freq 6
      pos 2284
      pos 2344
      pos 2366
      pos 2447
      pos 2602
      pos 2635
    doc 10
      freq 1
      pos 9498
    doc 11
      freq 2
      pos 337
      pos 6253
    doc 15
      freq 3
      pos 271
      pos 2794
      pos 2851
    doc 16
      freq 1
      pos 1246
    doc 17
      freq 1
      pos 1405
    skipList 
      level 0
        skipDoc 17
        skipDocFP 897304
        impacts 
          impact 
            freq 1
            norm 98
          impact 
            freq 3
            norm 104
          impact 
            freq 6
            norm 108
        impactsEnd 
  term failures
    doc 0
      freq 4
      pos 7420
      pos 7433
      pos 7992
      pos 7993
    doc 6
      freq 1
      pos 2438
    doc 8
      freq 1
      pos 1590
    doc 10
      freq 1
      pos 5678
  term fairchild
    doc 9
      freq 1
      pos 1771
  term faithfulness
    doc 3
      freq 1
      pos 1658
  term fall
    doc 0
      freq 1
      pos 4070
    doc 7
      freq 1
      pos 306
    doc 11
      freq 1
      pos 7088
    doc 12
      freq 1
      pos 3748
    doc 18
      freq 1
      pos 1608
  term falling
    doc 12
      freq 1
      pos 3644
  term falls
    doc 10
      freq 2
      pos 3273
      pos 4290
    doc 18
      freq 1
      pos 651
  term false
    doc 0
      freq 10
      pos 2798
      pos 3006
      pos 5014
      pos 5114
      pos 5217
      pos 5820
      pos 5930
      pos 6096
      pos 6127
      pos 12773
    doc 17
      freq 1
      pos 1423
  term falstrom
    doc 2
      freq 1
      pos 6357
  term faltstrom
    doc 10
      freq 2
      pos 12124
      pos 13338
  term familiar
    doc 2
      freq 2
      pos 4437
      pos 4512
    doc 3
      freq 1
      pos 439
    doc 9
      freq 1
      pos 582
  term family
    doc 4
      freq 1
      pos 5710
  term farinacc
    doc 1
      freq 1
      pos 8938
    doc 8
      freq 1
      pos 2063
  term farrel
    doc 0
      freq 1
      pos 15924
  term farrell
    doc 17
      freq 1
      pos 2074
  term farren
    doc 16
      freq 1
      pos 2359
  term fashion
    doc 10
      freq 1
      pos 12978
    doc 12
      freq 3
      pos 1787
      pos 4390
      pos 4809
  term fast
    doc 0
      freq 2
      pos 7054
      pos 7065
    doc 2
      freq 1
      pos 5969
    doc 13
      freq 1
      pos 4125
  term fault
    doc 1
      freq 1
      pos 5162
    doc 6
      freq 1
      pos 996
    doc 8
      freq 4
      pos 1603
      pos 1611
      pos 1620
      pos 1629
  term faulty
    doc 14
      freq 1
      pos 2149
  term favors
    doc 13
      freq 1
      pos 2494
  term fawerh2q
    doc 11
      freq 1
      pos 5958
  term fax
    doc 9
      freq 1
      pos 1783
  term fclpbs62
    doc 10
      freq 1
      pos 12809
  term fcmp0wwah5htnxu
    doc 10
      freq 1
      pos 6870
  term fcs
    doc 3
      freq 7
      pos 1367
      pos 1412
      pos 1439
      pos 1461
      pos 2145
      pos 2316
      pos 4642
    doc 8
      freq 3
      pos 1079
      pos 1082
      pos 1845
  term fcyul01avsgpzqxtxxbpo8o2qaxp4jtdubgchka6iykptmewcl
    doc 11
      freq 1
      pos 9892
  term fddi
    doc 7
      freq 4
      pos 720
      pos 968
      pos 2057
      pos 2420
  term fe
    doc 16
      freq 1
      pos 1529
  term fe80
    doc 12
      freq 1
      pos 1270
  term feasibl
    doc 10
      freq 1
      pos 9907
    doc 12
      freq 2
      pos 1572
      pos 9272
    doc 13
      freq 3
      pos 2454
      pos 2727
      pos 6576
  term featur
    doc 2
      freq 1
      pos 4702
    doc 13
      freq 1
      pos 4651
  term features
    doc 0
      freq 1
      pos 16724
    doc 3
      freq 2
      pos 1674
      pos 3474
    doc 11
      freq 3
      pos 2026
      pos 2730
      pos 7710
    doc 13
      freq 5
      pos 1284
      pos 2307
      pos 2649
      pos 2794
      pos 2829
  term feb
    doc 10
      freq 6
      pos 6356
      pos 6489
      pos 6641
      pos 7140
      pos 7239
      pos 7353
  term february
    doc 0
      freq 1
      pos 17126
    doc 2
      freq 4
      pos 2359
      pos 2873
      pos 2940
      pos 5746
    doc 3
      freq 4
      pos 4334
      pos 4549
      pos 4607
      pos 4640
    doc 5
      freq 2
      pos 4236
      pos 4394
    doc 8
      freq 2
      pos 2052
      pos 2125
    doc 10
      freq 1
      pos 13377
    doc 12
      freq 8
      pos 7156
      pos 7436
      pos 7452
      pos 7486
      pos 7509
      pos 7622
      pos 7756
      pos 7769
    doc 13
      freq 1
      pos 6826
    doc 14
      freq 2
      pos 5426
      pos 5503
    doc 15
      freq 1
      pos 3998
    skipList 
      level 0
        skipDoc 13
        skipDocFP 901511
        impacts 
          impact 
            freq 2
            norm 97
          impact 
            freq 4
            norm 107
          impact 
            freq 8
            norm 113
        impactsEnd 
  term fec
    doc 1
      freq 81
      pos 251
      pos 258
      pos 270
      pos 377
      pos 756
      pos 2093
      pos 2106
      pos 2122
      pos 2146
      pos 2164
      pos 2192
      pos 2200
      pos 2210
      pos 2216
      pos 2305
      pos 2311
      pos 2316
      pos 2321
      pos 2332
      pos 2335
      pos 2389
      pos 2393
      pos 2435
      pos 2440
      pos 2795
      pos 2852
      pos 2895
      pos 2899
      pos 2929
      pos 2978
      pos 2981
      pos 2987
      pos 3001
      pos 3030
      pos 3128
      pos 3592
      pos 3621
      pos 3623
      pos 3630
      pos 3852
      pos 3959
      pos 4221
      pos 4231
      pos 4280
      pos 4300
      pos 4311
      pos 4391
      pos 4397
      pos 4404
      pos 4563
      pos 4576
      pos 4594
      pos 4785
      pos 4798
      pos 5282
      pos 5287
      pos 5343
      pos 5391
      pos 5417
      pos 5431
      pos 5450
      pos 5463
      pos 5499
      pos 5531
      pos 5653
      pos 5732
      pos 5736
      pos 5857
      pos 5881
      pos 7105
      pos 7118
      pos 7155
      pos 7207
      pos 7298
      pos 7308
      pos 7477
      pos 7897
      pos 7906
      pos 7915
      pos 8755
      pos 8798
    doc 13
      freq 3
      pos 2145
      pos 2325
      pos 2342
  term fec0
    doc 12
      freq 1
      pos 1275
  term fed
    doc 10
      freq 1
      pos 12436
    doc 11
      freq 1
      pos 9843
  term federation
    doc 10
      freq 1
      pos 10955
  term federations
    doc 10
      freq 1
      pos 10934
  term fedorkow
    doc 1
      freq 1
      pos 8934
    doc 8
      freq 1
      pos 2059
  term fee
    doc 2
      freq 2
      pos 1904
      pos 1923
  term feedback
    doc 4
      freq 1
      pos 5513
    doc 7
      freq 1
      pos 1545
    doc 12
      freq 3
      pos 6775
      pos 6818
      pos 6828
  term feeds
    doc 11
      freq 1
      pos 913
  term feel
    doc 12
      freq 1
      pos 4998
    doc 15
      freq 1
      pos 3680
  term feldman
    doc 1
      freq 1
      pos 8916
    doc 3
      freq 1
      pos 4614
  term fellman
    doc 6
      freq 1
      pos 2906
  term ferguson
    doc 3
      freq 2
      pos 4964
      pos 4978
  term fetch
    doc 16
      freq 3
      pos 217
      pos 619
      pos 787
  term fetched
    doc 12
      freq 1
      pos 8164
  term fetches
    doc 11
      freq 1
      pos 8708
  term few
    doc 2
      freq 2
      pos 3902
      pos 4517
    doc 5
      freq 1
      pos 3191
    doc 10
      freq 3
      pos 546
      pos 1404
      pos 3477
    doc 12
      freq 1
      pos 8155
    doc 13
      freq 2
      pos 2753
      pos 3599
    doc 15
      freq 1
      pos 1706
    doc 18
      freq 1
      pos 880
  term fewer
    doc 14
      freq 1
      pos 5320
    doc 18
      freq 1
      pos 313
  term ff2z
    doc 10
      freq 1
      pos 12800
  term ffae3cbd2bff1675ddd5648e593dd647
    doc 11
      freq 1
      pos 3907
  term ffvgg0pdigkfrmlsj2plx6r5ny6jgcywt
    doc 10
      freq 1
      pos 12553
  term ffxqurwdaoxkglitu
    doc 11
      freq 1
      pos 10322
  term fgkgmhy4pnbdu53shvvlaix5tjqh0
    doc 10
      freq 1
      pos 12484
  term fhn2323orihawfdoa3o4r52o3irsdf
    doc 11
      freq 1
      pos 8339
  term fi7jv0lxjf8bx3
    doc 11
      freq 1
      pos 10441
  term fictional
    doc 14
      freq 1
      pos 2606
  term field
    doc 0
      freq 12
      pos 711
      pos 2822
      pos 7637
      pos 8045
      pos 8067
      pos 8110
      pos 8163
      pos 13428
      pos 13514
      pos 13995
      pos 14012
      pos 14108
    doc 1
      freq 33
      pos 473
      pos 484
      pos 790
      pos 850
      pos 1462
      pos 2587
      pos 2819
      pos 3026
      pos 3116
      pos 3131
      pos 3712
      pos 3718
      pos 3768
      pos 3817
      pos 3871
      pos 3886
      pos 4058
      pos 5116
      pos 5135
      pos 5147
      pos 5446
      pos 5507
      pos 5515
      pos 5547
      pos 5972
      pos 6010
      pos 6098
      pos 6114
      pos 7101
      pos 7163
      pos 7171
      pos 7223
      pos 7375
    doc 2
      freq 3
      pos 1649
      pos 1856
      pos 3421
    doc 3
      freq 10
      pos 3740
      pos 3794
      pos 3811
      pos 3836
      pos 3899
      pos 3929
      pos 5090
      pos 5104
      pos 5464
      pos 5508
    doc 4
      freq 28
      pos 629
      pos 647
      pos 666
      pos 713
      pos 939
      pos 1280
      pos 1337
      pos 2158
      pos 2205
      pos 2301
      pos 2356
      pos 2383
      pos 2460
      pos 2625
      pos 2651
      pos 2824
      pos 3069
      pos 3092
      pos 3305
      pos 3318
      pos 3358
      pos 3388
      pos 3478
      pos 3482
      pos 3487
      pos 3510
      pos 3769
      pos 4779
    doc 5
      freq 4
      pos 1722
      pos 1753
      pos 1851
      pos 2720
    doc 8
      freq 5
      pos 931
      pos 1099
      pos 1116
      pos 1256
      pos 1451
    doc 9
      freq 5
      pos 837
      pos 857
      pos 911
      pos 1279
      pos 1425
    doc 10
      freq 100
      pos 311
      pos 479
      pos 496
      pos 838
      pos 1031
      pos 1056
      pos 1111
      pos 1166
      pos 1191
      pos 1242
      pos 1326
      pos 1831
      pos 1879
      pos 1917
      pos 1944
      pos 1995
      pos 2003
      pos 2054
      pos 2067
      pos 2249
      pos 2269
      pos 2281
      pos 2364
      pos 2375
      pos 2379
      pos 2399
      pos 2438
      pos 2545
      pos 2731
      pos 2784
      pos 2896
      pos 2925
      pos 2976
      pos 3007
      pos 3024
      pos 3046
      pos 3293
      pos 3532
      pos 3540
      pos 3552
      pos 3637
      pos 3751
      pos 3997
      pos 4177
      pos 4202
      pos 4427
      pos 4497
      pos 4652
      pos 4658
      pos 4924
      pos 4932
      pos 4954
      pos 4973
      pos 4986
      pos 5001
      pos 5021
      pos 5055
      pos 5171
      pos 5183
      pos 5355
      pos 5368
      pos 5382
      pos 5553
      pos 5728
      pos 5784
      pos 5814
      pos 6132
      pos 7071
      pos 7164
      pos 7497
      pos 7543
      pos 7554
      pos 7611
      pos 7642
      pos 7706
      pos 7815
      pos 7891
      pos 7993
      pos 8003
      pos 8098
      pos 8245
      pos 8349
      pos 8370
      pos 8387
      pos 8403
      pos 8505
      pos 8646
      pos 8711
      pos 8748
      pos 8797
      pos 8837
      pos 8849
      pos 8921
      pos 9381
      pos 9580
      pos 9735
      pos 10124
      pos 10392
      pos 10817
      pos 11480
    doc 11
      freq 72
      pos 251
      pos 334
      pos 469
      pos 1007
      pos 1078
      pos 1168
      pos 1231
      pos 1244
      pos 1272
      pos 1287
      pos 1308
      pos 1313
      pos 1324
      pos 1362
      pos 1369
      pos 1410
      pos 1424
      pos 1431
      pos 1626
      pos 1670
      pos 1694
      pos 1759
      pos 1834
      pos 1889
      pos 2487
      pos 2499
      pos 2644
      pos 2738
      pos 2755
      pos 3567
      pos 3603
      pos 4223
      pos 4228
      pos 4244
      pos 4600
      pos 4622
      pos 4751
      pos 4813
      pos 4828
      pos 4959
      pos 4978
      pos 4994
      pos 4998
      pos 5098
      pos 5726
      pos 6035
      pos 6053
      pos 6076
      pos 6107
      pos 6273
      pos 6280
      pos 6399
      pos 6747
      pos 7332
      pos 7353
      pos 7369
      pos 7620
      pos 7707
      pos 7719
      pos 7903
      pos 7944
      pos 7966
      pos 7973
      pos 8242
      pos 8377
      pos 8389
      pos 8563
      pos 8593
      pos 8990
      pos 9035
      pos 9189
      pos 9240
    doc 13
      freq 1
      pos 1170
    doc 14
      freq 1
      pos 1835
    doc 17
      freq 7
      pos 1104
      pos 1108
      pos 1111
      pos 1194
      pos 1205
      pos 1706
      pos 1801
    doc 18
      freq 3
      pos 219
      pos 631
      pos 692
    skipList 
      level 0
        skipDoc 9
        skipDocFP 905842
        impacts 
          impact 
            freq 5
            norm 95
          impact 
            freq 10
            norm 107
          impact 
            freq 28
            norm 108
          impact 
            freq 33
            norm 113
        impactsEnd 
  term fielding
    doc 11
      freq 1
      pos 9678
    doc 13
      freq 1
      pos 6881
  term fields
    doc 0
      freq 1
      pos 12286
    doc 1
      freq 6
      pos 3310
      pos 3337
      pos 3357
      pos 3854
      pos 3933
      pos 5336
    doc 2
      freq 1
      pos 1882
    doc 3
      freq 2
      pos 3819
      pos 3844
    doc 4
      freq 17
      pos 970
      pos 1290
      pos 2150
      pos 2164
      pos 2816
      pos 2830
      pos 3061
      pos 3075
      pos 3297
      pos 3311
      pos 3590
      pos 3598
      pos 3761
      pos 3777
      pos 4332
      pos 4765
      pos 4795
    doc 10
      freq 8
      pos 142
      pos 5891
      pos 8234
      pos 8329
      pos 8338
      pos 8686
      pos 8762
      pos 9028
    doc 11
      freq 23
      pos 202
      pos 269
      pos 277
      pos 404
      pos 428
      pos 453
      pos 1235
      pos 1282
      pos 1341
      pos 1390
      pos 2467
      pos 2713
      pos 2720
      pos 4741
      pos 4860
      pos 4949
      pos 6510
      pos 6572
      pos 7169
      pos 7180
      pos 7560
      pos 7573
      pos 8081
    doc 16
      freq 2
      pos 489
      pos 1887
    doc 17
      freq 1
      pos 1101
    skipList 
      level 0
        skipDoc 16
        skipDocFP 910872
        impacts 
          impact 
            freq 2
            norm 99
          impact 
            freq 17
            norm 108
          impact 
            freq 23
            norm 114
        impactsEnd 
  term fifth
    doc 10
      freq 1
      pos 5197
    doc 12
      freq 1
      pos 679
  term figur
    doc 1
      freq 3
      pos 1052
      pos 1105
      pos 1465
    doc 3
      freq 9
      pos 635
      pos 648
      pos 744
      pos 842
      pos 908
      pos 4489
      pos 5040
      pos 5105
      pos 5775
    doc 6
      freq 1
      pos 2619
    doc 11
      freq 1
      pos 9824
  term figures
    doc 1
      freq 1
      pos 997
    doc 3
      freq 1
      pos 555
  term file
    doc 7
      freq 2
      pos 727
      pos 2064
    doc 10
      freq 3
      pos 12341
      pos 12349
      pos 12373
    doc 11
      freq 2
      pos 9766
      pos 9790
    doc 13
      freq 9
      pos 226
      pos 1312
      pos 2464
      pos 3311
      pos 3318
      pos 3357
      pos 3370
      pos 3373
      pos 3402
    doc 15
      freq 1
      pos 1045
    doc 17
      freq 2
      pos 1152
      pos 1171
  term file41
    doc 2
      freq 1
      pos 2447
  term files
    doc 7
      freq 1
      pos 2621
    doc 10
      freq 4
      pos 375
      pos 6168
      pos 12197
      pos 12449
    doc 11
      freq 2
      pos 873
      pos 9749
    doc 13
      freq 4
      pos 3329
      pos 3384
      pos 3467
      pos 3477
    doc 15
      freq 3
      pos 1914
      pos 3095
      pos 3109
  term fill
    doc 6
      freq 2
      pos 1348
      pos 1644
    doc 18
      freq 2
      pos 1305
      pos 1342
  term filling
    doc 3
      freq 1
      pos 5389
    doc 6
      freq 1
      pos 2320
  term filter
    doc 4
      freq 1
      pos 2353
    doc 13
      freq 1
      pos 4566
  term filtered
    doc 12
      freq 1
      pos 976
    doc 13
      freq 1
      pos 984
  term filtering
    doc 1
      freq 1
      pos 8606
    doc 2
      freq 4
      pos 247
      pos 3007
      pos 3401
      pos 4204
    doc 4
      freq 1
      pos 2621
    doc 12
      freq 3
      pos 5545
      pos 6891
      pos 7534
    doc 13
      freq 1
      pos 4441
  term fin
    doc 13
      freq 3
      pos 7015
      pos 7031
      pos 7050
  term final
    doc 7
      freq 2
      pos 451
      pos 1464
    doc 10
      freq 1
      pos 5276
    doc 11
      freq 1
      pos 9424
    doc 12
      freq 1
      pos 3537
    doc 13
      freq 1
      pos 3504
  term finally
    doc 4
      freq 1
      pos 1821
    doc 7
      freq 1
      pos 1655
    doc 10
      freq 4
      pos 3263
      pos 3379
      pos 8183
      pos 11364
    doc 13
      freq 2
      pos 797
      pos 960
    doc 14
      freq 1
      pos 2834
  term find
    doc 0
      freq 1
      pos 12933
    doc 4
      freq 1
      pos 5627
    doc 14
      freq 1
      pos 1846
  term finding
    doc 12
      freq 1
      pos 2377
  term finds
    doc 4
      freq 1
      pos 3383
  term fine
    doc 13
      freq 1
      pos 1774
  term fink
    doc 4
      freq 1
      pos 5483
    doc 12
      freq 1
      pos 7201
  term finland
    doc 12
      freq 1
      pos 9459
    doc 13
      freq 3
      pos 7018
      pos 7034
      pos 7053
  term fire
    doc 0
      freq 1
      pos 13402
  term firewall
    doc 4
      freq 1
      pos 2352
  term first
    doc 0
      freq 6
      pos 10651
      pos 10662
      pos 11692
      pos 12144
      pos 13054
      pos 14222
    doc 1
      freq 3
      pos 1498
      pos 5612
      pos 8244
    doc 2
      freq 1
      pos 3681
    doc 3
      freq 3
      pos 3365
      pos 3679
      pos 3695
    doc 4
      freq 1
      pos 1339
    doc 5
      freq 1
      pos 639
    doc 6
      freq 1
      pos 1994
    doc 7
      freq 3
      pos 1386
      pos 1585
      pos 1624
    doc 8
      freq 10
      pos 266
      pos 268
      pos 573
      pos 575
      pos 904
      pos 906
      pos 1229
      pos 1231
      pos 1410
      pos 1412
    doc 10
      freq 8
      pos 5121
      pos 5345
      pos 6472
      pos 7222
      pos 8411
      pos 9641
      pos 10162
      pos 10433
    doc 11
      freq 4
      pos 952
      pos 960
      pos 969
      pos 7363
    doc 12
      freq 15
      pos 581
      pos 1762
      pos 1790
      pos 3439
      pos 3465
      pos 3663
      pos 3761
      pos 3798
      pos 4727
      pos 4941
      pos 4953
      pos 5214
      pos 6299
      pos 6476
      pos 6565
    doc 14
      freq 4
      pos 647
      pos 2586
      pos 2636
      pos 2667
    doc 15
      freq 4
      pos 843
      pos 1777
      pos 1804
      pos 2043
    doc 16
      freq 2
      pos 150
      pos 1291
    doc 18
      freq 3
      pos 991
      pos 1530
      pos 1652
    skipList 
      level 0
        skipDoc 7
        skipDocFP 915459
        impacts 
          impact 
            freq 3
            norm 100
          impact 
            freq 6
            norm 120
        impactsEnd 
        skipDoc 18
        skipDocFP 915933
        impacts 
          impact 
            freq 10
            norm 97
          impact 
            freq 15
            norm 113
        impactsEnd 
  term fit
    doc 4
      freq 1
      pos 3365
    doc 9
      freq 1
      pos 1613
    doc 12
      freq 4
      pos 8088
      pos 8315
      pos 8573
      pos 8608
  term fitness
    doc 0
      freq 1
      pos 17327
    doc 1
      freq 1
      pos 9708
    doc 2
      freq 1
      pos 6505
    doc 3
      freq 1
      pos 6057
    doc 4
      freq 1
      pos 6212
    doc 5
      freq 1
      pos 4542
    doc 6
      freq 2
      pos 135
      pos 3342
    doc 7
      freq 1
      pos 3047
    doc 8
      freq 1
      pos 2264
    doc 9
      freq 1
      pos 1909
    doc 10
      freq 1
      pos 13570
    doc 11
      freq 1
      pos 10731
    doc 12
      freq 1
      pos 9581
    doc 13
      freq 1
      pos 7196
    doc 14
      freq 1
      pos 5662
    doc 15
      freq 1
      pos 4181
    doc 16
      freq 1
      pos 2792
    doc 17
      freq 1
      pos 2516
    doc 18
      freq 1
      pos 2304
    skipList 
      level 0
        skipDoc 7
        skipDocFP 917472
        impacts 
          impact 
            freq 1
            norm 100
          impact 
            freq 2
            norm 101
        impactsEnd 
        skipDoc 15
        skipDocFP 917791
        impacts 
          impact 
            freq 1
            norm 95
        impactsEnd 
  term fits
    doc 13
      freq 1
      pos 4689
  term fitting
    doc 12
      freq 2
      pos 8359
      pos 8439
  term five
    doc 11
      freq 1
      pos 4607
    doc 15
      freq 1
      pos 847
  term fix
    doc 12
      freq 5
      pos 1839
      pos 6687
      pos 6713
      pos 9318
      pos 9362
  term fixed
    doc 0
      freq 2
      pos 10723
      pos 10743
    doc 2
      freq 2
      pos 2720
      pos 2737
    doc 6
      freq 1
      pos 1660
    doc 8
      freq 3
      pos 71
      pos 76
      pos 1683
    doc 13
      freq 7
      pos 182
      pos 192
      pos 2070
      pos 2101
      pos 2429
      pos 2576
      pos 4158
  term fixes
    doc 10
      freq 1
      pos 12143
    doc 12
      freq 1
      pos 3950
  term fjunfz
    doc 11
      freq 1
      pos 10163
  term fjz48e1pxn3xs
    doc 10
      freq 1
      pos 12803
  term fk2ckiz5tet9vtz
    doc 11
      freq 1
      pos 10073
  term flab.fujitsu.co.jp
    doc 13
      freq 1
      pos 7006
  term flag
    doc 0
      freq 1
      pos 5090
    doc 1
      freq 1
      pos 2542
    doc 12
      freq 1
      pos 7402
    doc 16
      freq 4
      pos 561
      pos 652
      pos 701
      pos 807
    doc 17
      freq 1
      pos 633
  term flagged
    doc 17
      freq 1
      pos 639
  term flags
    doc 0
      freq 1
      pos 11972
    doc 15
      freq 1
      pos 782
    doc 16
      freq 2
      pos 610
      pos 660
  term flags.silent
    doc 16
      freq 1
      pos 2101
  term flavors
    doc 12
      freq 2
      pos 3284
      pos 7940
  term fletcher
    doc 0
      freq 2
      pos 11910
      pos 12207
  term flexibility
    doc 12
      freq 2
      pos 2031
      pos 4850
    doc 13
      freq 2
      pos 3694
      pos 3762
  term flexibl
    doc 6
      freq 1
      pos 720
    doc 13
      freq 2
      pos 1872
      pos 4280
  term flf3zfl3tn
    doc 11
      freq 1
      pos 10070
  term flick
    doc 2
      freq 2
      pos 3211
      pos 3228
  term flipping
    doc 12
      freq 1
      pos 8911
  term flood
    doc 0
      freq 1
      pos 2911
  term flooded
    doc 0
      freq 2
      pos 6000
      pos 6052
  term flooding
    doc 9
      freq 1
      pos 439
    doc 13
      freq 1
      pos 6455
  term floor
    doc 1
      freq 1
      pos 9346
    doc 3
      freq 1
      pos 4849
  term flores
    doc 3
      freq 1
      pos 4902
  term florid
    doc 17
      freq 1
      pos 2379
  term flow
    doc 3
      freq 6
      pos 250
      pos 301
      pos 3144
      pos 3153
      pos 3197
      pos 5280
    doc 6
      freq 21
      pos 237
      pos 250
      pos 1280
      pos 1320
      pos 1557
      pos 2053
      pos 2062
      pos 2314
      pos 2328
      pos 2384
      pos 2397
      pos 2408
      pos 2462
      pos 2476
      pos 2489
      pos 2562
      pos 2572
      pos 2627
      pos 2642
      pos 2675
      pos 2898
    doc 7
      freq 1
      pos 2108
    doc 11
      freq 1
      pos 3763
  term flowed
    doc 16
      freq 1
      pos 2036
  term flows
    doc 6
      freq 7
      pos 375
      pos 852
      pos 2283
      pos 2511
      pos 2531
      pos 2535
      pos 2604
    doc 11
      freq 1
      pos 9704
  term floyd
    doc 2
      freq 2
      pos 3606
      pos 3628
  term fluffy
    doc 10
      freq 1
      pos 13452
  term flushing
    doc 12
      freq 1
      pos 3148
  term fmezudxynh8a1
    doc 11
      freq 1
      pos 10136
  term fo
    doc 10
      freq 1
      pos 12810
    doc 14
      freq 11
      pos 3571
      pos 3748
      pos 3820
      pos 4184
      pos 4206
      pos 4251
      pos 4272
      pos 4466
      pos 4488
      pos 4549
      pos 4570
  term fo3gyp21ly0rny9obglaaqjq11ipgeohi0x
    doc 11
      freq 1
      pos 10200
  term focus
    doc 11
      freq 1
      pos 695
    doc 15
      freq 1
      pos 504
  term focused
    doc 6
      freq 1
      pos 900
    doc 13
      freq 1
      pos 4189
  term focuses
    doc 5
      freq 1
      pos 750
    doc 6
      freq 1
      pos 613
  term focusing
    doc 15
      freq 1
      pos 3418
  term fold
    doc 11
      freq 2
      pos 932
      pos 7766
  term folding
    doc 11
      freq 2
      pos 985
      pos 1213
  term follow
    doc 2
      freq 1
      pos 1243
    doc 3
      freq 2
      pos 3441
      pos 3461
    doc 10
      freq 3
      pos 4156
      pos 5615
      pos 10917
  term followed
    doc 1
      freq 1
      pos 6901
    doc 4
      freq 1
      pos 4375
    doc 5
      freq 1
      pos 2971
    doc 7
      freq 2
      pos 211
      pos 224
    doc 10
      freq 1
      pos 5280
    doc 11
      freq 1
      pos 8421
    doc 12
      freq 1
      pos 2696
  term following
    doc 0
      freq 5
      pos 457
      pos 10281
      pos 15817
      pos 15904
      pos 16645
    doc 1
      freq 12
      pos 995
      pos 2280
      pos 2314
      pos 2337
      pos 4957
      pos 5650
      pos 5679
      pos 5879
      pos 7386
      pos 7771
      pos 7821
      pos 8002
    doc 2
      freq 1
      pos 5287
    doc 3
      freq 7
      pos 553
      pos 856
      pos 1319
      pos 2776
      pos 3952
      pos 5019
      pos 5650
    doc 4
      freq 12
      pos 583
      pos 757
      pos 1351
      pos 1645
      pos 2058
      pos 3497
      pos 4764
      pos 4800
      pos 5056
      pos 5096
      pos 5124
      pos 5545
    doc 5
      freq 10
      pos 653
      pos 883
      pos 1884
      pos 2657
      pos 2846
      pos 3703
      pos 3768
      pos 3821
      pos 3975
      pos 4036
    doc 6
      freq 2
      pos 2019
      pos 2170
    doc 8
      freq 3
      pos 346
      pos 402
      pos 940
    doc 9
      freq 1
      pos 393
    doc 10
      freq 31
      pos 2326
      pos 2412
      pos 3918
      pos 4111
      pos 4203
      pos 4795
      pos 4881
      pos 5316
      pos 5774
      pos 5975
      pos 6063
      pos 6191
      pos 6304
      pos 6468
      pos 6558
      pos 6605
      pos 6819
      pos 6943
      pos 7218
      pos 7263
      pos 7321
      pos 8315
      pos 10754
      pos 11506
      pos 11606
      pos 11701
      pos 11802
      pos 11896
      pos 12186
      pos 12363
      pos 12842
    doc 11
      freq 11
      pos 943
      pos 1054
      pos 1073
      pos 1607
      pos 2029
      pos 2437
      pos 2733
      pos 4604
      pos 9546
      pos 9738
      pos 9780
    doc 12
      freq 1
      pos 2540
    doc 13
      freq 4
      pos 1107
      pos 2313
      pos 2752
      pos 2835
    doc 14
      freq 6
      pos 349
      pos 571
      pos 1187
      pos 1955
      pos 2700
      pos 2888
    doc 15
      freq 2
      pos 617
      pos 3836
    doc 16
      freq 9
      pos 548
      pos 753
      pos 832
      pos 1413
      pos 1723
      pos 1744
      pos 1865
      pos 2123
      pos 2260
    doc 17
      freq 1
      pos 1858
    doc 18
      freq 7
      pos 777
      pos 786
      pos 847
      pos 986
      pos 1235
      pos 1377
      pos 1874
    skipList 
      level 0
        skipDoc 8
        skipDocFP 923316
        impacts 
          impact 
            freq 3
            norm 97
          impact 
            freq 10
            norm 104
          impact 
            freq 12
            norm 108
        impactsEnd 
        skipDoc 16
        skipDocFP 924276
        impacts 
          impact 
            freq 1
            norm 95
          impact 
            freq 9
            norm 99
          impact 
            freq 11
            norm 114
          impact 
            freq 31
            norm 116
        impactsEnd 
  term follows
    doc 0
      freq 25
      pos 2566
      pos 2689
      pos 5746
      pos 5892
      pos 6915
      pos 6962
      pos 7045
      pos 7137
      pos 7180
      pos 10124
      pos 10185
      pos 10218
      pos 10276
      pos 10490
      pos 10524
      pos 10575
      pos 10697
      pos 10781
      pos 11394
      pos 11421
      pos 11473
      pos 11520
      pos 11550
      pos 11584
      pos 11628
    doc 1
      freq 10
      pos 2449
      pos 2550
      pos 3635
      pos 5319
      pos 5495
      pos 5632
      pos 6015
      pos 6526
      pos 6784
      pos 7151
    doc 3
      freq 4
      pos 2012
      pos 3222
      pos 3630
      pos 5330
    doc 4
      freq 2
      pos 1106
      pos 4129
    doc 7
      freq 1
      pos 334
    doc 8
      freq 2
      pos 944
      pos 1581
    doc 9
      freq 1
      pos 715
    doc 10
      freq 6
      pos 1151
      pos 2761
      pos 2918
      pos 5259
      pos 5508
      pos 12157
    doc 16
      freq 2
      pos 698
      pos 732
    skipList 
      level 0
        skipDoc 10
        skipDocFP 926220
        impacts 
          impact 
            freq 1
            norm 95
          impact 
            freq 2
            norm 97
          impact 
            freq 4
            norm 107
          impact 
            freq 10
            norm 113
          impact 
            freq 25
            norm 120
        impactsEnd 
  term fon
    doc 14
      freq 4
      pos 3142
      pos 3214
      pos 4887
      pos 4953
    doc 18
      freq 1
      pos 1390
  term foo
    doc 10
      freq 9
      pos 12218
      pos 12224
      pos 12234
      pos 12245
      pos 12258
      pos 12281
      pos 12312
      pos 12320
      pos 12329
    doc 14
      freq 4
      pos 3285
      pos 5006
      pos 5141
      pos 5159
    doc 16
      freq 3
      pos 2008
      pos 2319
      pos 2361
  term foo.example.com
    doc 12
      freq 4
      pos 2835
      pos 2836
      pos 2841
      pos 2914
    doc 14
      freq 11
      pos 2966
      pos 3250
      pos 3251
      pos 3522
      pos 3535
      pos 4157
      pos 4159
      pos 4886
      pos 4986
      pos 5009
      pos 5140
    doc 18
      freq 3
      pos 1369
      pos 1456
      pos 1541
  term fool
    doc 9
      freq 1
      pos 875
  term fooled
    doc 9
      freq 1
      pos 1472
  term fooooooooooooooooooooooooooooooooooooooo
    doc 14
      freq 1
      pos 4448
  term foooooooooooooooooooooooooooooooooooooooooooooo
    doc 14
      freq 6
      pos 4175
      pos 4195
      pos 4241
      pos 4262
      pos 4539
      pos 4560
  term fooooooooooooooooooooooooooooooooooooooop.ooooo
    doc 14
      freq 1
      pos 4479
  term football
    doc 13
      freq 1
      pos 3128
  term footnot
    doc 15
      freq 1
      pos 3719
  term for
    doc 0
      freq 187
      pos 7
      pos 20
      pos 40
      pos 49
      pos 65
      pos 100
      pos 116
      pos 135
      pos 198
      pos 308
      pos 333
      pos 350
      pos 374
      pos 421
      pos 443
      pos 534
      pos 581
      pos 1083
      pos 1092
      pos 1129
      pos 1148
      pos 1194
      pos 1230
      pos 1440
      pos 1625
      pos 1672
      pos 1679
      pos 1712
      pos 1715
      pos 1721
      pos 1756
      pos 1807
      pos 1977
      pos 2005
      pos 2048
      pos 2083
      pos 2157
      pos 2363
      pos 2396
      pos 2421
      pos 2506
      pos 2579
      pos 2629
      pos 2927
      pos 3079
      pos 3190
      pos 3196
      pos 3261
      pos 3291
      pos 3503
      pos 3709
      pos 3731
      pos 3787
      pos 3793
      pos 3898
      pos 4221
      pos 4243
      pos 4299
      pos 4305
      pos 4410
      pos 4685
      pos 4793
      pos 4977
      pos 5071
      pos 5080
      pos 5398
      pos 5444
      pos 5448
      pos 5604
      pos 5694
      pos 5875
      pos 6310
      pos 6317
      pos 6416
      pos 6458
      pos 6479
      pos 6515
      pos 6559
      pos 6684
      pos 6694
      pos 6744
      pos 6862
      pos 7216
      pos 7635
      pos 7763
      pos 7784
      pos 8072
      pos 8114
      pos 8167
      pos 9218
      pos 9264
      pos 9305
      pos 9509
      pos 10084
      pos 10129
      pos 10269
      pos 10480
      pos 10647
      pos 10726
      pos 10759
      pos 10954
      pos 11164
      pos 11169
      pos 11269
      pos 11428
      pos 11510
      pos 11574
      pos 11834
      pos 11856
      pos 11912
      pos 11936
      pos 12009
      pos 12187
      pos 12209
      pos 12290
      pos 12305
      pos 12325
      pos 12340
      pos 12364
      pos 12389
      pos 12417
      pos 12442
      pos 12480
      pos 12506
      pos 12536
      pos 12580
      pos 12607
      pos 12655
      pos 12676
      pos 12731
      pos 12738
      pos 12752
      pos 12910
      pos 13093
      pos 13164
      pos 13207
      pos 13266
      pos 13483
      pos 13581
      pos 13673
      pos 13775
      pos 13811
      pos 13848
      pos 13883
      pos 13932
      pos 13973
      pos 14002
      pos 14060
      pos 14189
      pos 14393
      pos 14421
      pos 14432
      pos 14459
      pos 14483
      pos 14519
      pos 14558
      pos 14587
      pos 14598
      pos 14625
      pos 14649
      pos 14685
      pos 14709
      pos 14733
      pos 14773
      pos 15856
      pos 15895
      pos 15906
      pos 16141
      pos 16241
      pos 16615
      pos 16738
      pos 16743
      pos 16764
      pos 16897
      pos 16904
      pos 16946
      pos 16968
      pos 17005
      pos 17024
      pos 17070
      pos 17088
      pos 17120
      pos 17156
      pos 17186
      pos 17328
      pos 17454
      pos 17528
    doc 1
      freq 111
      pos 7
      pos 57
      pos 66
      pos 82
      pos 170
      pos 184
      pos 324
      pos 335
      pos 455
      pos 564
      pos 585
      pos 633
      pos 653
      pos 743
      pos 761
      pos 809
      pos 814
      pos 824
      pos 945
      pos 1112
      pos 1313
      pos 1379
      pos 1564
      pos 1604
      pos 1672
      pos 1689
      pos 1776
      pos 1810
      pos 1895
      pos 2023
      pos 2151
      pos 2202
      pos 2253
      pos 2293
      pos 2328
      pos 2411
      pos 2428
      pos 2524
      pos 2576
      pos 2682
      pos 2708
      pos 2846
      pos 3351
      pos 3598
      pos 3723
      pos 3808
      pos 4143
      pos 4264
      pos 4323
      pos 4475
      pos 4492
      pos 4662
      pos 4729
      pos 4928
      pos 4971
      pos 4977
      pos 5202
      pos 5405
      pos 5473
      pos 5566
      pos 5668
      pos 5767
      pos 5780
      pos 5916
      pos 6088
      pos 6190
      pos 6291
      pos 6321
      pos 6374
      pos 6397
      pos 6430
      pos 6469
      pos 6486
      pos 6502
      pos 6514
      pos 6633
      pos 6650
      pos 6710
      pos 6777
      pos 6859
      pos 6864
      pos 6948
      pos 6953
      pos 6983
      pos 7072
      pos 7249
      pos 7499
      pos 7525
      pos 7609
      pos 7621
      pos 7627
      pos 7775
      pos 7825
      pos 7919
      pos 7939
      pos 7979
      pos 8592
      pos 8640
      pos 8655
      pos 8836
      pos 8899
      pos 8958
      pos 9037
      pos 9061
      pos 9083
      pos 9110
      pos 9141
      pos 9477
      pos 9709
      pos 9835
      pos 9909
    doc 2
      freq 101
      pos 7
      pos 30
      pos 520
      pos 530
      pos 579
      pos 646
      pos 699
      pos 818
      pos 902
      pos 1105
      pos 1183
      pos 1403
      pos 1526
      pos 1565
      pos 1586
      pos 1618
      pos 1644
      pos 1656
      pos 1750
      pos 1778
      pos 1830
      pos 1871
      pos 1891
      pos 1911
      pos 1924
      pos 1954
      pos 1994
      pos 2002
      pos 2018
      pos 2173
      pos 2236
      pos 2257
      pos 2313
      pos 2403
      pos 2467
      pos 2483
      pos 2504
      pos 2559
      pos 2567
      pos 2661
      pos 2686
      pos 2709
      pos 2719
      pos 2728
      pos 2735
      pos 2910
      pos 2931
      pos 3001
      pos 3057
      pos 3081
      pos 3123
      pos 3149
      pos 3217
      pos 3234
      pos 3253
      pos 3297
      pos 3314
      pos 3339
      pos 3356
      pos 3379
      pos 3395
      pos 3477
      pos 3522
      pos 3613
      pos 3634
      pos 3792
      pos 3846
      pos 3888
      pos 3991
      pos 4070
      pos 4088
      pos 4095
      pos 4126
      pos 4189
      pos 4195
      pos 4270
      pos 4464
      pos 4527
      pos 4786
      pos 4794
      pos 5009
      pos 5044
      pos 5147
      pos 5494
      pos 5506
      pos 5514
      pos 5557
      pos 5563
      pos 5719
      pos 5728
      pos 5805
      pos 5818
      pos 5863
      pos 5906
      pos 5948
      pos 6051
      pos 6174
      pos 6316
      pos 6506
      pos 6632
      pos 6706
    doc 3
      freq 48
      pos 7
      pos 32
      pos 51
      pos 60
      pos 76
      pos 148
      pos 496
      pos 522
      pos 549
      pos 701
      pos 768
      pos 978
      pos 1026
      pos 1095
      pos 1103
      pos 1476
      pos 1713
      pos 1811
      pos 1861
      pos 1993
      pos 2386
      pos 2664
      pos 3009
      pos 3192
      pos 3410
      pos 3435
      pos 3484
      pos 3489
      pos 3700
      pos 3854
      pos 4220
      pos 4326
      pos 4341
      pos 4412
      pos 4454
      pos 4497
      pos 4577
      pos 5027
      pos 5241
      pos 5316
      pos 5352
      pos 5436
      pos 5447
      pos 5569
      pos 5832
      pos 6058
      pos 6184
      pos 6258
    doc 4
      freq 109
      pos 6
      pos 33
      pos 53
      pos 62
      pos 78
      pos 127
      pos 144
      pos 157
      pos 244
      pos 255
      pos 297
      pos 341
      pos 382
      pos 425
      pos 474
      pos 576
      pos 745
      pos 755
      pos 796
      pos 825
      pos 840
      pos 847
      pos 888
      pos 910
      pos 943
      pos 975
      pos 987
      pos 1014
      pos 1209
      pos 1325
      pos 1328
      pos 1331
      pos 1371
      pos 1604
      pos 1692
      pos 1758
      pos 1887
      pos 1957
      pos 1975
      pos 2017
      pos 2052
      pos 2064
      pos 2080
      pos 2208
      pos 2259
      pos 2282
      pos 2317
      pos 2342
      pos 2364
      pos 2445
      pos 2575
      pos 2600
      pos 2633
      pos 2670
      pos 2685
      pos 2721
      pos 2967
      pos 3095
      pos 3204
      pos 3440
      pos 3470
      pos 3630
      pos 3688
      pos 3696
      pos 3802
      pos 3854
      pos 3862
      pos 4052
      pos 4092
      pos 4240
      pos 4502
      pos 4746
      pos 4790
      pos 4820
      pos 4843
      pos 4888
      pos 4964
      pos 5009
      pos 5025
      pos 5029
      pos 5052
      pos 5101
      pos 5136
      pos 5159
      pos 5165
      pos 5203
      pos 5238
      pos 5255
      pos 5272
      pos 5313
      pos 5357
      pos 5374
      pos 5404
      pos 5430
      pos 5520
      pos 5534
      pos 5597
      pos 5725
      pos 5819
      pos 5837
      pos 5883
      pos 5905
      pos 5965
      pos 6008
      pos 6038
      pos 6104
      pos 6213
      pos 6339
      pos 6413
    doc 5
      freq 82
      pos 6
      pos 37
      pos 46
      pos 62
      pos 197
      pos 204
      pos 207
      pos 436
      pos 501
      pos 510
      pos 566
      pos 581
      pos 610
      pos 615
      pos 649
      pos 661
      pos 697
      pos 909
      pos 918
      pos 934
      pos 959
      pos 962
      pos 1004
      pos 1028
      pos 1093
      pos 1158
      pos 1160
      pos 1171
      pos 1210
      pos 1244
      pos 1325
      pos 1335
      pos 1383
      pos 1396
      pos 1508
      pos 1638
      pos 1655
      pos 1731
      pos 1757
      pos 1778
      pos 1871
      pos 1908
      pos 1929
      pos 2012
      pos 2022
      pos 2075
      pos 2106
      pos 2154
      pos 2194
      pos 2509
      pos 2536
      pos 2583
      pos 2766
      pos 2775
      pos 2837
      pos 2896
      pos 3077
      pos 3188
      pos 3278
      pos 3311
      pos 3701
      pos 3720
      pos 3752
      pos 3784
      pos 3813
      pos 3851
      pos 3881
      pos 3940
      pos 3963
      pos 3983
      pos 4000
      pos 4029
      pos 4076
      pos 4097
      pos 4102
      pos 4127
      pos 4148
      pos 4248
      pos 4270
      pos 4543
      pos 4669
      pos 4743
    doc 6
      freq 55
      pos 6
      pos 33
      pos 69
      pos 127
      pos 165
      pos 172
      pos 197
      pos 247
      pos 251
      pos 279
      pos 316
      pos 350
      pos 439
      pos 665
      pos 669
      pos 711
      pos 778
      pos 797
      pos 832
      pos 842
      pos 854
      pos 893
      pos 1018
      pos 1103
      pos 1203
      pos 1233
      pos 1379
      pos 1384
      pos 1437
      pos 1462
      pos 1909
      pos 1970
      pos 1992
      pos 2012
      pos 2083
      pos 2165
      pos 2296
      pos 2350
      pos 2470
      pos 2510
      pos 2527
      pos 2533
      pos 2631
      pos 2650
      pos 2696
      pos 2744
      pos 2812
      pos 2910
      pos 3019
      pos 3076
      pos 3165
      pos 3176
      pos 3343
      pos 3469
      pos 3543
    doc 7
      freq 70
      pos 6
      pos 44
      pos 168
      pos 268
      pos 359
      pos 382
      pos 404
      pos 526
      pos 627
      pos 729
      pos 749
      pos 798
      pos 813
      pos 827
      pos 841
      pos 857
      pos 880
      pos 896
      pos 926
      pos 989
      pos 1016
      pos 1026
      pos 1059
      pos 1144
      pos 1188
      pos 1266
      pos 1319
      pos 1338
      pos 1363
      pos 1381
      pos 1412
      pos 1670
      pos 1698
      pos 1963
      pos 1975
      pos 2011
      pos 2066
      pos 2078
      pos 2102
      pos 2134
      pos 2143
      pos 2208
      pos 2223
      pos 2237
      pos 2251
      pos 2267
      pos 2290
      pos 2308
      pos 2325
      pos 2344
      pos 2360
      pos 2390
      pos 2439
      pos 2452
      pos 2477
      pos 2556
      pos 2571
      pos 2636
      pos 2655
      pos 2666
      pos 2712
      pos 2745
      pos 2761
      pos 2802
      pos 2811
      pos 2856
      pos 2872
      pos 3048
      pos 3174
      pos 3248
    doc 8
      freq 44
      pos 6
      pos 22
      pos 41
      pos 50
      pos 79
      pos 189
      pos 206
      pos 274
      pos 287
      pos 385
      pos 389
      pos 432
      pos 476
      pos 560
      pos 587
      pos 594
      pos 801
      pos 891
      pos 926
      pos 972
      pos 1128
      pos 1216
      pos 1251
      pos 1266
      pos 1397
      pos 1442
      pos 1446
      pos 1461
      pos 1560
      pos 1631
      pos 1649
      pos 1672
      pos 1732
      pos 1767
      pos 1912
      pos 1933
      pos 1950
      pos 1972
      pos 1997
      pos 2117
      pos 2156
      pos 2265
      pos 2391
      pos 2465
    doc 9
      freq 50
      pos 6
      pos 39
      pos 48
      pos 64
      pos 99
      pos 110
      pos 161
      pos 234
      pos 311
      pos 469
      pos 504
      pos 559
      pos 597
      pos 606
      pos 687
      pos 699
      pos 732
      pos 743
      pos 818
      pos 864
      pos 887
      pos 921
      pos 938
      pos 994
      pos 1031
      pos 1141
      pos 1154
      pos 1156
      pos 1214
      pos 1238
      pos 1259
      pos 1265
      pos 1374
      pos 1385
      pos 1401
      pos 1415
      pos 1435
      pos 1457
      pos 1478
      pos 1579
      pos 1638
      pos 1641
      pos 1670
      pos 1695
      pos 1710
      pos 1729
      pos 1800
      pos 1910
      pos 2036
      pos 2110
    doc 10
      freq 192
      pos 6
      pos 20
      pos 42
      pos 51
      pos 67
      pos 103
      pos 126
      pos 144
      pos 149
      pos 156
      pos 214
      pos 220
      pos 245
      pos 412
      pos 427
      pos 471
      pos 563
      pos 587
      pos 707
      pos 868
      pos 896
      pos 922
      pos 1041
      pos 1097
      pos 1145
      pos 1195
      pos 1262
      pos 1411
      pos 1431
      pos 1466
      pos 1478
      pos 1584
      pos 1590
      pos 1600
      pos 1632
      pos 1742
      pos 1847
      pos 1931
      pos 2104
      pos 2233
      pos 2262
      pos 2335
      pos 2407
      pos 2430
      pos 2457
      pos 2463
      pos 2473
      pos 2496
      pos 2738
      pos 2754
      pos 2869
      pos 2872
      pos 2952
      pos 3106
      pos 3127
      pos 3134
      pos 3281
      pos 3464
      pos 3479
      pos 3576
      pos 3630
      pos 3701
      pos 3718
      pos 3731
      pos 3763
      pos 3801
      pos 3872
      pos 3933
      pos 3954
      pos 4040
      pos 4170
      pos 4206
      pos 4311
      pos 4336
      pos 4400
      pos 4567
      pos 4603
      pos 4676
      pos 4742
      pos 4790
      pos 5061
      pos 5085
      pos 5101
      pos 5223
      pos 5285
      pos 5420
      pos 5441
      pos 5455
      pos 5474
      pos 5554
      pos 5623
      pos 5692
      pos 5706
      pos 5739
      pos 5875
      pos 5914
      pos 5924
      pos 6014
      pos 6084
      pos 6095
      pos 6150
      pos 6169
      pos 6452
      pos 6808
      pos 7058
      pos 7175
      pos 7256
      pos 7427
      pos 7467
      pos 7484
      pos 7522
      pos 7526
      pos 7539
      pos 7674
      pos 7714
      pos 7739
      pos 7763
      pos 7783
      pos 7856
      pos 7862
      pos 7907
      pos 7961
      pos 8106
      pos 8127
      pos 8159
      pos 8300
      pos 8378
      pos 8426
      pos 8436
      pos 8547
      pos 8651
      pos 8840
      pos 9011
      pos 9017
      pos 9060
      pos 9084
      pos 9157
      pos 9206
      pos 9463
      pos 9538
      pos 9599
      pos 9670
      pos 9684
      pos 9772
      pos 9984
      pos 9999
      pos 10045
      pos 10100
      pos 10116
      pos 10225
      pos 10307
      pos 10486
      pos 10625
      pos 10706
      pos 10724
      pos 10805
      pos 10854
      pos 10899
      pos 10930
      pos 10938
      pos 10980
      pos 11097
      pos 11229
      pos 11317
      pos 11344
      pos 11471
      pos 11473
      pos 11771
      pos 11785
      pos 11937
      pos 11951
      pos 11991
      pos 12017
      pos 12033
      pos 12076
      pos 12136
      pos 12172
      pos 12214
      pos 12305
      pos 12342
      pos 12860
      pos 12966
      pos 13031
      pos 13052
      pos 13121
      pos 13141
      pos 13192
      pos 13302
      pos 13318
      pos 13571
      pos 13697
      pos 13771
    doc 11
      freq 32
      pos 7
      pos 46
      pos 719
      pos 1125
      pos 1268
      pos 1408
      pos 1624
      pos 3934
      pos 4424
      pos 4534
      pos 4587
      pos 4618
      pos 4851
      pos 4992
      pos 5437
      pos 5862
      pos 6299
      pos 6736
      pos 7026
      pos 7497
      pos 7601
      pos 8691
      pos 8715
      pos 8806
      pos 8908
      pos 9375
      pos 9503
      pos 9528
      pos 9536
      pos 10732
      pos 10858
      pos 10932
    doc 12
      freq 141
      pos 6
      pos 36
      pos 100
      pos 104
      pos 110
      pos 113
      pos 137
      pos 247
      pos 270
      pos 290
      pos 314
      pos 320
      pos 348
      pos 453
      pos 532
      pos 539
      pos 577
      pos 673
      pos 720
      pos 738
      pos 787
      pos 797
      pos 947
      pos 1054
      pos 1139
      pos 1154
      pos 1431
      pos 1531
      pos 1698
      pos 1815
      pos 1935
      pos 1953
      pos 2015
      pos 2022
      pos 2025
      pos 2034
      pos 2058
      pos 2067
      pos 2146
      pos 2188
      pos 2190
      pos 2202
      pos 2292
      pos 2312
      pos 2350
      pos 2381
      pos 2450
      pos 2469
      pos 2506
      pos 2527
      pos 2584
      pos 2608
      pos 2737
      pos 2755
      pos 2796
      pos 2812
      pos 2820
      pos 2823
      pos 2905
      pos 2939
      pos 2969
      pos 2985
      pos 3028
      pos 3112
      pos 3163
      pos 3185
      pos 3219
      pos 3263
      pos 3417
      pos 3448
      pos 3508
      pos 3533
      pos 3556
      pos 3707
      pos 3718
      pos 3915
      pos 4015
      pos 4057
      pos 4093
      pos 4139
      pos 4331
      pos 4420
      pos 4497
      pos 4507
      pos 4525
      pos 4710
      pos 4738
      pos 4790
      pos 4796
      pos 4848
      pos 5033
      pos 5206
      pos 5283
      pos 5299
      pos 5305
      pos 5651
      pos 5824
      pos 6012
      pos 6064
      pos 6106
      pos 6376
      pos 6507
      pos 6624
      pos 6628
      pos 6842
      pos 6965
      pos 7091
      pos 7131
      pos 7189
      pos 7249
      pos 7286
      pos 7291
      pos 7308
      pos 7379
      pos 7395
      pos 7499
      pos 7535
      pos 7560
      pos 7580
      pos 7734
      pos 7831
      pos 7898
      pos 7967
      pos 8017
      pos 8058
      pos 8060
      pos 8287
      pos 8900
      pos 8990
      pos 9066
      pos 9082
      pos 9101
      pos 9106
      pos 9150
      pos 9319
      pos 9325
      pos 9333
      pos 9363
      pos 9582
      pos 9708
      pos 9782
    doc 13
      freq 129
      pos 6
      pos 32
      pos 45
      pos 78
      pos 83
      pos 92
      pos 111
      pos 125
      pos 270
      pos 321
      pos 355
      pos 368
      pos 406
      pos 556
      pos 646
      pos 706
      pos 723
      pos 759
      pos 815
      pos 1089
      pos 1141
      pos 1156
      pos 1300
      pos 1420
      pos 1427
      pos 1462
      pos 1529
      pos 1547
      pos 1619
      pos 1630
      pos 1654
      pos 1676
      pos 1694
      pos 1802
      pos 1821
      pos 1848
      pos 1861
      pos 1871
      pos 1908
      pos 1966
      pos 2109
      pos 2173
      pos 2229
      pos 2388
      pos 2481
      pos 2523
      pos 2565
      pos 2602
      pos 2674
      pos 2692
      pos 2746
      pos 2784
      pos 2936
      pos 2969
      pos 3005
      pos 3147
      pos 3151
      pos 3160
      pos 3170
      pos 3211
      pos 3231
      pos 3303
      pos 3352
      pos 3385
      pos 3387
      pos 3428
      pos 3438
      pos 3580
      pos 3664
      pos 3763
      pos 3809
      pos 3837
      pos 3892
      pos 3914
      pos 3949
      pos 3965
      pos 4064
      pos 4114
      pos 4134
      pos 4150
      pos 4209
      pos 4245
      pos 4300
      pos 4330
      pos 4528
      pos 4659
      pos 4675
      pos 4692
      pos 4699
      pos 4832
      pos 4882
      pos 4985
      pos 5020
      pos 5219
      pos 5225
      pos 5236
      pos 5297
      pos 5382
      pos 5400
      pos 5435
      pos 5478
      pos 5550
      pos 5578
      pos 5644
      pos 5713
      pos 5732
      pos 5766
      pos 5782
      pos 6011
      pos 6138
      pos 6175
      pos 6244
      pos 6272
      pos 6302
      pos 6333
      pos 6347
      pos 6382
      pos 6513
      pos 6655
      pos 6693
      pos 6715
      pos 6740
      pos 6868
      pos 6945
      pos 6978
      pos 7085
      pos 7197
      pos 7323
      pos 7397
    doc 14
      freq 31
      pos 6
      pos 33
      pos 50
      pos 74
      pos 91
      pos 172
      pos 288
      pos 328
      pos 540
      pos 579
      pos 1124
      pos 1256
      pos 1297
      pos 1353
      pos 1764
      pos 1856
      pos 2391
      pos 2578
      pos 2594
      pos 2621
      pos 2713
      pos 2717
      pos 2748
      pos 2771
      pos 2775
      pos 5352
      pos 5416
      pos 5442
      pos 5663
      pos 5789
      pos 5863
    doc 15
      freq 85
      pos 6
      pos 44
      pos 78
      pos 114
      pos 126
      pos 270
      pos 353
      pos 378
      pos 410
      pos 468
      pos 509
      pos 562
      pos 585
      pos 591
      pos 671
      pos 676
      pos 776
      pos 800
      pos 928
      pos 933
      pos 1046
      pos 1050
      pos 1134
      pos 1149
      pos 1266
      pos 1302
      pos 1347
      pos 1350
      pos 1419
      pos 1440
      pos 1542
      pos 1622
      pos 1686
      pos 1694
      pos 1696
      pos 1730
      pos 1865
      pos 1889
      pos 1904
      pos 2025
      pos 2037
      pos 2052
      pos 2111
      pos 2194
      pos 2258
      pos 2345
      pos 2358
      pos 2411
      pos 2469
      pos 2489
      pos 2513
      pos 2519
      pos 2545
      pos 2576
      pos 2639
      pos 2641
      pos 2788
      pos 2793
      pos 2826
      pos 3067
      pos 3082
      pos 3099
      pos 3110
      pos 3182
      pos 3241
      pos 3284
      pos 3328
      pos 3353
      pos 3381
      pos 3417
      pos 3530
      pos 3541
      pos 3560
      pos 3700
      pos 3744
      pos 3770
      pos 3838
      pos 3890
      pos 3930
      pos 3955
      pos 3972
      pos 3988
      pos 4182
      pos 4308
      pos 4382
    doc 16
      freq 39
      pos 6
      pos 38
      pos 47
      pos 63
      pos 306
      pos 319
      pos 328
      pos 406
      pos 434
      pos 811
      pos 915
      pos 994
      pos 1062
      pos 1129
      pos 1146
      pos 1244
      pos 1269
      pos 1344
      pos 1352
      pos 1586
      pos 1594
      pos 1613
      pos 1792
      pos 1820
      pos 1837
      pos 1888
      pos 1945
      pos 2081
      pos 2173
      pos 2201
      pos 2313
      pos 2385
      pos 2409
      pos 2428
      pos 2445
      pos 2613
      pos 2793
      pos 2919
      pos 2993
    doc 17
      freq 33
      pos 6
      pos 35
      pos 44
      pos 60
      pos 332
      pos 346
      pos 364
      pos 410
      pos 607
      pos 684
      pos 709
      pos 757
      pos 780
      pos 831
      pos 989
      pos 1039
      pos 1065
      pos 1129
      pos 1159
      pos 1188
      pos 1296
      pos 1535
      pos 1557
      pos 1819
      pos 1958
      pos 1989
      pos 2018
      pos 2032
      pos 2084
      pos 2258
      pos 2517
      pos 2643
      pos 2717
    doc 18
      freq 22
      pos 6
      pos 44
      pos 53
      pos 69
      pos 112
      pos 329
      pos 581
      pos 969
      pos 973
      pos 1047
      pos 1364
      pos 1540
      pos 1625
      pos 1698
      pos 1920
      pos 2049
      pos 2094
      pos 2117
      pos 2131
      pos 2305
      pos 2431
      pos 2505
    skipList 
      level 0
        skipDoc 7
        skipDocFP 929040
        impacts 
          impact 
            freq 70
            norm 100
          impact 
            freq 82
            norm 104
          impact 
            freq 109
            norm 108
          impact 
            freq 111
            norm 113
          impact 
            freq 187
            norm 120
        impactsEnd 
        skipDoc 15
        skipDocFP 940589
        impacts 
          impact 
            freq 50
            norm 95
          impact 
            freq 85
            norm 104
          impact 
            freq 129
            norm 109
          impact 
            freq 141
            norm 113
          impact 
            freq 192
            norm 116
        impactsEnd 
  term forbes
    doc 6
      freq 1
      pos 3186
  term forbidding
    doc 18
      freq 1
      pos 282
  term force
    doc 0
      freq 4
      pos 4929
      pos 16068
      pos 16399
      pos 17294
    doc 1
      freq 1
      pos 9675
    doc 2
      freq 1
      pos 6472
    doc 3
      freq 1
      pos 6024
    doc 4
      freq 1
      pos 6179
    doc 5
      freq 1
      pos 4509
    doc 6
      freq 1
      pos 3309
    doc 7
      freq 1
      pos 3014
    doc 8
      freq 1
      pos 2231
    doc 9
      freq 1
      pos 1876
    doc 10
      freq 1
      pos 13537
    doc 11
      freq 1
      pos 10698
    doc 12
      freq 1
      pos 9548
    doc 13
      freq 1
      pos 7163
    doc 14
      freq 1
      pos 5629
    doc 15
      freq 1
      pos 4148
    doc 16
      freq 1
      pos 2759
    doc 17
      freq 1
      pos 2483
    doc 18
      freq 1
      pos 2271
    skipList 
      level 0
        skipDoc 7
        skipDocFP 953556
        impacts 
          impact 
            freq 1
            norm 100
          impact 
            freq 4
            norm 120
        impactsEnd 
        skipDoc 15
        skipDocFP 953908
        impacts 
          impact 
            freq 1
            norm 95
        impactsEnd 
  term forced
    doc 13
      freq 1
      pos 2709
    doc 15
      freq 1
      pos 3036
  term ford
    doc 10
      freq 1
      pos 13231
    doc 17
      freq 1
      pos 2051
  term forever
    doc 15
      freq 1
      pos 2436
  term forged
    doc 13
      freq 1
      pos 5758
  term forgo
    doc 12
      freq 1
      pos 6337
  term form
    doc 0
      freq 9
      pos 2411
      pos 7872
      pos 7995
      pos 10451
      pos 14414
      pos 14442
      pos 14580
      pos 14608
      pos 16193
    doc 1
      freq 1
      pos 3144
    doc 4
      freq 1
      pos 4603
    doc 10
      freq 10
      pos 1470
      pos 2979
      pos 3304
      pos 4492
      pos 5633
      pos 7531
      pos 7606
      pos 7622
      pos 11527
      pos 11534
    doc 11
      freq 4
      pos 860
      pos 1267
      pos 4626
      pos 6286
    doc 12
      freq 9
      pos 3870
      pos 3927
      pos 4281
      pos 4307
      pos 4990
      pos 5039
      pos 5372
      pos 5596
      pos 5648
    doc 13
      freq 1
      pos 5959
    doc 15
      freq 1
      pos 3173
    doc 16
      freq 3
      pos 690
      pos 718
      pos 1421
    doc 17
      freq 1
      pos 1033
    skipList 
      level 0
        skipDoc 15
        skipDocFP 955053
        impacts 
          impact 
            freq 1
            norm 104
          impact 
            freq 9
            norm 113
          impact 
            freq 10
            norm 116
        impactsEnd 
  term formal
    doc 2
      freq 1
      pos 5110
    doc 16
      freq 2
      pos 1410
      pos 1434
  term format
    doc 0
      freq 1
      pos 10347
    doc 1
      freq 2
      pos 5057
      pos 5227
    doc 2
      freq 4
      pos 1617
      pos 1634
      pos 1637
      pos 1828
    doc 3
      freq 1
      pos 487
    doc 4
      freq 8
      pos 106
      pos 163
      pos 325
      pos 532
      pos 585
      pos 640
      pos 5990
      pos 5997
    doc 5
      freq 1
      pos 1993
    doc 6
      freq 1
      pos 768
    doc 7
      freq 2
      pos 728
      pos 2065
    doc 10
      freq 2
      pos 6203
      pos 13179
    doc 11
      freq 1
      pos 9624
    doc 12
      freq 2
      pos 779
      pos 1391
    doc 13
      freq 7
      pos 613
      pos 2926
      pos 3403
      pos 3641
      pos 5198
      pos 5304
      pos 5533
    doc 14
      freq 1
      pos 2086
    doc 15
      freq 1
      pos 653
    doc 16
      freq 5
      pos 1072
      pos 1077
      pos 2035
      pos 2564
      pos 2582
    skipList 
      level 0
        skipDoc 7
        skipDocFP 956300
        impacts 
          impact 
            freq 2
            norm 100
          impact 
            freq 8
            norm 108
        impactsEnd 
  term formation
    doc 2
      freq 1
      pos 3739
    doc 13
      freq 1
      pos 1228
  term formats
    doc 1
      freq 1
      pos 9129
    doc 4
      freq 4
      pos 754
      pos 986
      pos 2063
      pos 6010
    doc 8
      freq 1
      pos 941
    doc 11
      freq 1
      pos 9029
    doc 13
      freq 6
      pos 648
      pos 3646
      pos 3683
      pos 5273
      pos 5315
      pos 5569
  term formatting
    doc 11
      freq 1
      pos 803
  term formed
    doc 0
      freq 5
      pos 510
      pos 3843
      pos 4343
      pos 10739
      pos 11207
    doc 2
      freq 3
      pos 4407
      pos 5193
      pos 5276
    doc 10
      freq 1
      pos 5410
    doc 11
      freq 16
      pos 1357
      pos 2126
      pos 2318
      pos 2439
      pos 2509
      pos 2670
      pos 2716
      pos 3487
      pos 3587
      pos 3733
      pos 3970
      pos 4084
      pos 7301
      pos 7447
      pos 7912
      pos 8399
  term former
    doc 10
      freq 1
      pos 771
    doc 12
      freq 1
      pos 2867
  term forming
    doc 0
      freq 1
      pos 3540
    doc 10
      freq 5
      pos 3469
      pos 3544
      pos 3721
      pos 4588
      pos 8807
  term forms
    doc 10
      freq 1
      pos 10028
    doc 12
      freq 1
      pos 8543
  term formulated
    doc 2
      freq 1
      pos 6004
    doc 11
      freq 1
      pos 9026
  term formulating
    doc 10
      freq 1
      pos 7659
  term formulation
    doc 10
      freq 1
      pos 5309
  term forth
    doc 0
      freq 1
      pos 17250
    doc 1
      freq 1
      pos 9631
    doc 2
      freq 1
      pos 6428
    doc 3
      freq 1
      pos 5980
    doc 4
      freq 1
      pos 6135
    doc 5
      freq 1
      pos 4465
    doc 6
      freq 1
      pos 3265
    doc 7
      freq 1
      pos 2970
    doc 8
      freq 1
      pos 2187
    doc 9
      freq 1
      pos 1832
    doc 10
      freq 1
      pos 13493
    doc 11
      freq 1
      pos 10654
    doc 12
      freq 1
      pos 9504
    doc 13
      freq 1
      pos 7119
    doc 14
      freq 1
      pos 5585
    doc 15
      freq 1
      pos 4104
    doc 16
      freq 1
      pos 2715
    doc 17
      freq 1
      pos 2439
    doc 18
      freq 1
      pos 2227
    skipList 
      level 0
        skipDoc 7
        skipDocFP 958968
        impacts 
          impact 
            freq 1
            norm 100
        impactsEnd 
        skipDoc 15
        skipDocFP 959273
        impacts 
          impact 
            freq 1
            norm 95
        impactsEnd 
  term forthcoming
    doc 11
      freq 1
      pos 4437
  term fortunately
    doc 10
      freq 1
      pos 7525
  term forward
    doc 0
      freq 3
      pos 12523
      pos 12958
      pos 16031
    doc 4
      freq 1
      pos 2875
    doc 10
      freq 6
      pos 2482
      pos 3384
      pos 3655
      pos 5925
      pos 7715
      pos 9539
    doc 11
      freq 6
      pos 1421
      pos 1864
      pos 2513
      pos 3299
      pos 8429
      pos 8572
    doc 12
      freq 19
      pos 116
      pos 354
      pos 703
      pos 756
      pos 813
      pos 1306
      pos 4206
      pos 4218
      pos 4250
      pos 4347
      pos 5055
      pos 5085
      pos 5123
      pos 5364
      pos 5442
      pos 5590
      pos 5601
      pos 6949
      pos 7941
    doc 13
      freq 2
      pos 2142
      pos 5003
  term forwarded
    doc 0
      freq 2
      pos 10557
      pos 11613
    doc 2
      freq 1
      pos 1060
    doc 3
      freq 1
      pos 984
    doc 4
      freq 4
      pos 1874
      pos 2552
      pos 4476
      pos 5931
    doc 7
      freq 1
      pos 610
    doc 11
      freq 4
      pos 3310
      pos 5908
      pos 5923
      pos 7948
  term forwarder
    doc 1
      freq 6
      pos 3089
      pos 3099
      pos 3155
      pos 3190
      pos 4440
      pos 4672
    doc 3
      freq 2
      pos 2131
      pos 2311
  term forwarders
    doc 1
      freq 6
      pos 3077
      pos 3124
      pos 3212
      pos 3241
      pos 4458
      pos 4534
  term forwarding
    doc 0
      freq 1
      pos 10267
    doc 1
      freq 4
      pos 2024
      pos 5187
      pos 7459
      pos 7681
    doc 3
      freq 1
      pos 1414
    doc 4
      freq 3
      pos 1829
      pos 2295
      pos 5653
    doc 8
      freq 2
      pos 1587
      pos 1595
    doc 10
      freq 1
      pos 4740
  term forwards
    doc 3
      freq 1
      pos 2414
    doc 10
      freq 9
      pos 6309
      pos 6351
      pos 6636
      pos 6707
      pos 6948
      pos 6986
      pos 7123
      pos 7336
      pos 7386
    doc 11
      freq 60
      pos 474
      pos 1166
      pos 1181
      pos 1343
      pos 1470
      pos 1991
      pos 2214
      pos 2374
      pos 2589
      pos 2689
      pos 3149
      pos 3342
      pos 3377
      pos 3524
      pos 3627
      pos 3792
      pos 4285
      pos 4453
      pos 4669
      pos 4769
      pos 4812
      pos 4928
      pos 5168
      pos 5295
      pos 5326
      pos 5471
      pos 5599
      pos 5624
      pos 5765
      pos 5821
      pos 5945
      pos 6167
      pos 6357
      pos 6449
      pos 6566
      pos 6610
      pos 6686
      pos 6777
      pos 6869
      pos 7114
      pos 7390
      pos 7521
      pos 7658
      pos 7747
      pos 7864
      pos 7935
      pos 8051
      pos 8094
      pos 8139
      pos 8182
      pos 8347
      pos 8549
      pos 8561
      pos 8592
      pos 8629
      pos 8738
      pos 8828
      pos 8927
      pos 9082
      pos 9238
  term found
    doc 0
      freq 2
      pos 4623
      pos 17415
    doc 1
      freq 2
      pos 4061
      pos 9796
    doc 2
      freq 4
      pos 1129
      pos 4599
      pos 4758
      pos 6593
    doc 3
      freq 3
      pos 1226
      pos 3778
      pos 6145
    doc 4
      freq 2
      pos 4112
      pos 6300
    doc 5
      freq 2
      pos 1104
      pos 4630
    doc 6
      freq 1
      pos 3430
    doc 7
      freq 2
      pos 497
      pos 3135
    doc 8
      freq 2
      pos 217
      pos 2352
    doc 9
      freq 2
      pos 571
      pos 1997
    doc 10
      freq 1
      pos 13658
    doc 11
      freq 2
      pos 7494
      pos 10819
    doc 12
      freq 4
      pos 727
      pos 3951
      pos 6514
      pos 9669
    doc 13
      freq 1
      pos 7284
    doc 14
      freq 1
      pos 5750
    doc 15
      freq 1
      pos 4269
    doc 16
      freq 2
      pos 1431
      pos 2880
    doc 17
      freq 2
      pos 767
      pos 2604
    doc 18
      freq 1
      pos 2392
    skipList 
      level 0
        skipDoc 7
        skipDocFP 962986
        impacts 
          impact 
            freq 2
            norm 100
          impact 
            freq 3
            norm 107
          impact 
            freq 4
            norm 108
        impactsEnd 
        skipDoc 15
        skipDocFP 963440
        impacts 
          impact 
            freq 2
            norm 95
          impact 
            freq 4
            norm 113
        impactsEnd 
  term foundational
    doc 10
      freq 1
      pos 9192
  term four
    doc 5
      freq 1
      pos 2008
    doc 7
      freq 1
      pos 1477
    doc 14
      freq 1
      pos 2567
    doc 15
      freq 2
      pos 844
      pos 3994
  term fourth
    doc 5
      freq 1
      pos 808
    doc 10
      freq 1
      pos 5195
    doc 12
      freq 1
      pos 667
  term fprwrx
    doc 10
      freq 1
      pos 6909
  term fq9i
    doc 10
      freq 1
      pos 12653
  term fqdn
    doc 12
      freq 2
      pos 7817
      pos 7868
  term fraction
    doc 4
      freq 1
      pos 1914
  term frag
    doc 3
      freq 4
      pos 1620
      pos 4241
      pos 4256
      pos 4627
    doc 8
      freq 2
      pos 1076
      pos 1830
  term fragment
    doc 0
      freq 3
      pos 929
      pos 1542
      pos 3377
    doc 3
      freq 1
      pos 4246
    doc 4
      freq 3
      pos 3086
      pos 3184
      pos 5687
    doc 13
      freq 1
      pos 5482
  term fragmentation
    doc 3
      freq 2
      pos 1615
      pos 4634
    doc 8
      freq 2
      pos 1074
      pos 1837
    doc 12
      freq 3
      pos 174
      pos 612
      pos 1087
    doc 13
      freq 2
      pos 5399
      pos 5454
  term fragmented
    doc 12
      freq 1
      pos 7963
  term fragmenting
    doc 12
      freq 1
      pos 1095
    doc 15
      freq 1
      pos 2780
  term fragments
    doc 12
      freq 1
      pos 2830
  term frame
    doc 1
      freq 8
      pos 111
      pos 437
      pos 1613
      pos 1641
      pos 1712
      pos 1730
      pos 9027
      pos 9040
    doc 3
      freq 58
      pos 239
      pos 243
      pos 470
      pos 943
      pos 973
      pos 1137
      pos 1189
      pos 1364
      pos 1371
      pos 1375
      pos 1395
      pos 1403
      pos 1416
      pos 1511
      pos 1528
      pos 1597
      pos 1700
      pos 1848
      pos 2134
      pos 2167
      pos 2305
      pos 2336
      pos 2339
      pos 2364
      pos 2452
      pos 2509
      pos 2528
      pos 2531
      pos 2547
      pos 2561
      pos 2584
      pos 2593
      pos 2671
      pos 2707
      pos 2742
      pos 2757
      pos 2908
      pos 2920
      pos 2963
      pos 2977
      pos 3004
      pos 3019
      pos 3025
      pos 3043
      pos 3085
      pos 3100
      pos 3116
      pos 3391
      pos 3471
      pos 3504
      pos 3732
      pos 3853
      pos 4197
      pos 4235
      pos 4652
      pos 5294
      pos 5298
      pos 5408
    doc 7
      freq 1
      pos 2844
    doc 8
      freq 11
      pos 631
      pos 636
      pos 722
      pos 726
      pos 787
      pos 790
      pos 1067
      pos 1071
      pos 1855
      pos 1903
      pos 1915
    doc 11
      freq 1
      pos 3721
  term frames
    doc 0
      freq 13
      pos 7314
      pos 7383
      pos 7416
      pos 7612
      pos 7710
      pos 8042
      pos 8434
      pos 8502
      pos 8560
      pos 8618
      pos 8675
      pos 8720
      pos 8765
    doc 1
      freq 2
      pos 7956
      pos 9088
    doc 3
      freq 21
      pos 664
      pos 981
      pos 1109
      pos 1352
      pos 1828
      pos 1901
      pos 2416
      pos 2931
      pos 2985
      pos 3063
      pos 3181
      pos 3292
      pos 3451
      pos 3562
      pos 4248
      pos 5319
      pos 5332
      pos 5351
      pos 5368
      pos 5514
      pos 5835
    doc 8
      freq 2
      pos 1977
      pos 2001
  term framework
    doc 0
      freq 7
      pos 146
      pos 197
      pos 212
      pos 400
      pos 1047
      pos 16730
      pos 17190
    doc 2
      freq 3
      pos 2812
      pos 4452
      pos 4967
    doc 5
      freq 2
      pos 605
      pos 736
    doc 10
      freq 1
      pos 13371
    doc 13
      freq 4
      pos 80
      pos 705
      pos 1546
      pos 6867
  term frameworks
    doc 0
      freq 1
      pos 17032
    doc 17
      freq 1
      pos 2141
  term framing
    doc 3
      freq 1
      pos 3109
    doc 11
      freq 3
      pos 4571
      pos 8250
      pos 8301
  term franc
    doc 17
      freq 1
      pos 2395
  term francis
    doc 17
      freq 13
      pos 4
      pos 149
      pos 508
      pos 808
      pos 1046
      pos 1392
      pos 1841
      pos 2106
      pos 2144
      pos 2313
      pos 2369
      pos 2399
      pos 2731
  term francois
    doc 11
      freq 1
      pos 9562
  term fred
    doc 1
      freq 1
      pos 4499
    doc 2
      freq 2
      pos 3467
      pos 3565
    doc 4
      freq 1
      pos 5500
  term frederick
    doc 6
      freq 1
      pos 3067
  term fredett
    doc 1
      freq 1
      pos 8918
    doc 3
      freq 1
      pos 4616
  term free
    doc 2
      freq 1
      pos 742
    doc 10
      freq 1
      pos 9834
    doc 12
      freq 1
      pos 8810
    doc 13
      freq 1
      pos 5066
  term freed
    doc 16
      freq 1
      pos 2570
  term freely
    doc 13
      freq 2
      pos 6145
      pos 6184
  term frequency
    doc 6
      freq 1
      pos 1124
  term frequently
    doc 1
      freq 1
      pos 3205
    doc 2
      freq 1
      pos 766
    doc 11
      freq 1
      pos 7358
  term fresh
    doc 5
      freq 2
      pos 3508
      pos 3532
    doc 9
      freq 1
      pos 1330
  term freshness
    doc 5
      freq 1
      pos 3492
    doc 17
      freq 1
      pos 1578
  term fri
    doc 11
      freq 1
      pos 6185
  term friedman
    doc 6
      freq 1
      pos 3044
  term friendly
    doc 13
      freq 1
      pos 4203
    doc 18
      freq 1
      pos 1893
  term fries
    doc 5
      freq 20
      pos 4
      pos 242
      pos 345
      pos 781
      pos 1138
      pos 1469
      pos 1736
      pos 2039
      pos 2350
      pos 2547
      pos 2728
      pos 3042
      pos 3352
      pos 3653
      pos 3905
      pos 4105
      pos 4341
      pos 4399
      pos 4426
      pos 4757
  term from
    doc 0
      freq 53
      pos 347
      pos 361
      pos 389
      pos 561
      pos 877
      pos 1016
      pos 1030
      pos 1040
      pos 1045
      pos 1052
      pos 1057
      pos 1064
      pos 1961
      pos 3339
      pos 3387
      pos 3844
      pos 3991
      pos 4037
      pos 4344
      pos 6822
      pos 7331
      pos 7359
      pos 7489
      pos 7594
      pos 7639
      pos 8070
      pos 8112
      pos 8165
      pos 8941
      pos 9162
      pos 9548
      pos 9745
      pos 9771
      pos 9933
      pos 10367
      pos 10439
      pos 10638
      pos 10754
      pos 10848
      pos 10879
      pos 10912
      pos 11208
      pos 11388
      pos 12591
      pos 13307
      pos 13609
      pos 13699
      pos 13802
      pos 14009
      pos 16369
      pos 16439
      pos 16530
      pos 17471
    doc 1
      freq 28
      pos 527
      pos 861
      pos 1005
      pos 1200
      pos 1222
      pos 1592
      pos 1624
      pos 1650
      pos 1763
      pos 3386
      pos 3403
      pos 3454
      pos 4201
      pos 4445
      pos 5776
      pos 5859
      pos 6173
      pos 6264
      pos 7456
      pos 7912
      pos 7964
      pos 8079
      pos 8141
      pos 8168
      pos 8263
      pos 8458
      pos 8569
      pos 9852
    doc 2
      freq 17
      pos 547
      pos 656
      pos 1515
      pos 1540
      pos 1937
      pos 2263
      pos 2753
      pos 2776
      pos 2833
      pos 3806
      pos 3832
      pos 4216
      pos 4467
      pos 5141
      pos 5815
      pos 6014
      pos 6649
    doc 3
      freq 18
      pos 467
      pos 563
      pos 883
      pos 1368
      pos 1404
      pos 2389
      pos 2410
      pos 2512
      pos 2526
      pos 2567
      pos 2708
      pos 2787
      pos 2932
      pos 3926
      pos 4059
      pos 5653
      pos 5810
      pos 6201
    doc 4
      freq 34
      pos 569
      pos 721
      pos 730
      pos 1245
      pos 1321
      pos 1357
      pos 1496
      pos 1536
      pos 1739
      pos 1774
      pos 2154
      pos 2516
      pos 2820
      pos 3065
      pos 3301
      pos 3765
      pos 3785
      pos 3811
      pos 3820
      pos 4148
      pos 4152
      pos 4202
      pos 4770
      pos 4814
      pos 4833
      pos 4864
      pos 4970
      pos 5455
      pos 5549
      pos 5591
      pos 5662
      pos 5853
      pos 5998
      pos 6356
    doc 5
      freq 7
      pos 379
      pos 1248
      pos 1892
      pos 3242
      pos 3807
      pos 4023
      pos 4686
    doc 6
      freq 10
      pos 235
      pos 981
      pos 1086
      pos 1388
      pos 1505
      pos 1570
      pos 1833
      pos 1902
      pos 2250
      pos 3486
    doc 7
      freq 11
      pos 26
      pos 304
      pos 374
      pos 521
      pos 929
      pos 1160
      pos 1263
      pos 1293
      pos 1546
      pos 2393
      pos 3191
    doc 8
      freq 7
      pos 456
      pos 590
      pos 915
      pos 1240
      pos 1421
      pos 1562
      pos 2408
    doc 9
      freq 6
      pos 757
      pos 780
      pos 825
      pos 1461
      pos 1512
      pos 2053
    doc 10
      freq 102
      pos 477
      pos 494
      pos 618
      pos 836
      pos 1029
      pos 1054
      pos 1069
      pos 1109
      pos 1164
      pos 1189
      pos 1202
      pos 1240
      pos 1324
      pos 1829
      pos 1877
      pos 1915
      pos 1993
      pos 2052
      pos 2065
      pos 2351
      pos 2360
      pos 2362
      pos 2656
      pos 2729
      pos 2782
      pos 2821
      pos 2894
      pos 2923
      pos 2962
      pos 3005
      pos 3022
      pos 3044
      pos 3199
      pos 3346
      pos 3550
      pos 3591
      pos 3618
      pos 3635
      pos 3749
      pos 3964
      pos 3974
      pos 4175
      pos 4425
      pos 4454
      pos 4495
      pos 4650
      pos 4654
      pos 4656
      pos 4864
      pos 4922
      pos 4969
      pos 4983
      pos 5039
      pos 5250
      pos 5351
      pos 5353
      pos 5364
      pos 5378
      pos 6338
      pos 6623
      pos 6748
      pos 6988
      pos 7125
      pos 7338
      pos 7495
      pos 7552
      pos 7609
      pos 7640
      pos 7704
      pos 7813
      pos 7889
      pos 8070
      pos 8096
      pos 8232
      pos 8243
      pos 8347
      pos 8368
      pos 8423
      pos 8755
      pos 8779
      pos 8995
      pos 9266
      pos 9285
      pos 9323
      pos 9345
      pos 9379
      pos 9578
      pos 9733
      pos 9892
      pos 10057
      pos 10390
      pos 10408
      pos 10815
      pos 11077
      pos 11086
      pos 11103
      pos 11194
      pos 11245
      pos 11258
      pos 12230
      pos 12338
      pos 13714
    doc 11
      freq 68
      pos 1462
      pos 1615
      pos 1664
      pos 1692
      pos 1709
      pos 1766
      pos 1966
      pos 2056
      pos 2206
      pos 2366
      pos 2465
      pos 2564
      pos 2642
      pos 2682
      pos 2753
      pos 3336
      pos 3371
      pos 3518
      pos 3621
      pos 3817
      pos 4023
      pos 4146
      pos 4279
      pos 4458
      pos 4674
      pos 4916
      pos 5040
      pos 5162
      pos 5320
      pos 5465
      pos 5629
      pos 5805
      pos 5939
      pos 6161
      pos 6351
      pos 6451
      pos 6508
      pos 6612
      pos 6688
      pos 6771
      pos 6863
      pos 6984
      pos 7073
      pos 7108
      pos 7176
      pos 7384
      pos 7515
      pos 7569
      pos 7643
      pos 7711
      pos 7741
      pos 7858
      pos 8045
      pos 8092
      pos 8155
      pos 8166
      pos 8248
      pos 8331
      pos 8492
      pos 8609
      pos 8740
      pos 8830
      pos 8921
      pos 9076
      pos 9195
      pos 9254
      pos 9609
      pos 10875
    doc 12
      freq 28
      pos 980
      pos 1094
      pos 2042
      pos 2181
      pos 2616
      pos 2954
      pos 3009
      pos 3102
      pos 3124
      pos 3368
      pos 3907
      pos 4223
      pos 5071
      pos 5362
      pos 5506
      pos 5763
      pos 5890
      pos 6608
      pos 6760
      pos 7913
      pos 8020
      pos 8028
      pos 8511
      pos 8903
      pos 9166
      pos 9171
      pos 9209
      pos 9725
    doc 13
      freq 25
      pos 249
      pos 991
      pos 1263
      pos 1370
      pos 1396
      pos 1445
      pos 1512
      pos 1946
      pos 2045
      pos 2422
      pos 2646
      pos 2671
      pos 2801
      pos 3629
      pos 3754
      pos 4032
      pos 4249
      pos 4477
      pos 5183
      pos 5664
      pos 5947
      pos 6130
      pos 6581
      pos 6666
      pos 7340
    doc 14
      freq 2
      pos 1179
      pos 5806
    doc 15
      freq 23
      pos 157
      pos 839
      pos 874
      pos 1037
      pos 1090
      pos 1158
      pos 1253
      pos 1312
      pos 1792
      pos 1853
      pos 1860
      pos 1993
      pos 2228
      pos 2396
      pos 2541
      pos 2758
      pos 3047
      pos 3427
      pos 3454
      pos 3647
      pos 3703
      pos 3751
      pos 4325
    doc 16
      freq 10
      pos 874
      pos 1023
      pos 1101
      pos 1457
      pos 1467
      pos 1955
      pos 1990
      pos 2323
      pos 2358
      pos 2936
    doc 17
      freq 8
      pos 1169
      pos 1363
      pos 1539
      pos 1969
      pos 2201
      pos 2208
      pos 2233
      pos 2660
    doc 18
      freq 5
      pos 1128
      pos 1220
      pos 1827
      pos 1911
      pos 2448
    skipList 
      level 0
        skipDoc 7
        skipDocFP 970304
        impacts 
          impact 
            freq 11
            norm 100
          impact 
            freq 18
            norm 107
          impact 
            freq 34
            norm 108
          impact 
            freq 53
            norm 120
        impactsEnd 
        skipDoc 15
        skipDocFP 973160
        impacts 
          impact 
            freq 6
            norm 95
          impact 
            freq 7
            norm 97
          impact 
            freq 23
            norm 104
          impact 
            freq 25
            norm 109
          impact 
            freq 28
            norm 113
          impact 
            freq 68
            norm 114
          impact 
            freq 102
            norm 116
        impactsEnd 
  term fromparam
    doc 11
      freq 1
      pos 1972
  term frost
    doc 8
      freq 1
      pos 2017
  term frystyk
    doc 13
      freq 1
      pos 6887
  term fs1uqt0
    doc 11
      freq 1
      pos 10325
  term fsjkfjtldzjvqxhkcsklpcfrcfb
    doc 11
      freq 1
      pos 10181
  term fsoqxuef
    doc 10
      freq 1
      pos 6899
  term fsuswapubro1vexs74dhs9ywxj3bynxn3ypqqtfiq5
    doc 11
      freq 1
      pos 10236
  term ft7tqp9lflhtmed
    doc 11
      freq 1
      pos 9975
  term ftam
    doc 7
      freq 2
      pos 781
      pos 2186
  term ftp
    doc 7
      freq 2
      pos 780
      pos 2185
    doc 10
      freq 1
      pos 13267
    doc 13
      freq 1
      pos 6789
  term ftp.ee.lbl.gov
    doc 13
      freq 1
      pos 6790
  term fujitsu
    doc 13
      freq 2
      pos 9
      pos 6991
  term fulfill
    doc 13
      freq 1
      pos 3863
  term fulfilled
    doc 12
      freq 1
      pos 4174
  term fulfilling
    doc 13
      freq 1
      pos 4871
  term full
    doc 0
      freq 5
      pos 1231
      pos 1805
      pos 11982
      pos 16736
      pos 17223
    doc 1
      freq 1
      pos 9604
    doc 2
      freq 1
      pos 6401
    doc 3
      freq 1
      pos 5953
    doc 4
      freq 1
      pos 6108
    doc 5
      freq 2
      pos 2467
      pos 4438
    doc 6
      freq 1
      pos 3233
    doc 7
      freq 2
      pos 1313
      pos 2943
    doc 8
      freq 1
      pos 2160
    doc 9
      freq 1
      pos 1805
    doc 10
      freq 2
      pos 12997
      pos 13466
    doc 11
      freq 1
      pos 10627
    doc 12
      freq 2
      pos 8151
      pos 9477
    doc 13
      freq 2
      pos 6557
      pos 7092
    doc 14
      freq 2
      pos 2821
      pos 5558
    doc 15
      freq 4
      pos 757
      pos 1378
      pos 3668
      pos 4077
    doc 16
      freq 1
      pos 2688
    doc 17
      freq 1
      pos 2412
    doc 18
      freq 1
      pos 2200
    skipList 
      level 0
        skipDoc 7
        skipDocFP 979531
        impacts 
          impact 
            freq 2
            norm 100
          impact 
            freq 5
            norm 120
        impactsEnd 
        skipDoc 15
        skipDocFP 979928
        impacts 
          impact 
            freq 1
            norm 95
          impact 
            freq 4
            norm 104
        impactsEnd 
  term fully
    doc 0
      freq 2
      pos 6627
      pos 14561
    doc 1
      freq 1
      pos 5008
    doc 4
      freq 1
      pos 523
    doc 12
      freq 2
      pos 281
      pos 2518
    doc 13
      freq 1
      pos 1539
    doc 15
      freq 2
      pos 2676
      pos 3869
    doc 18
      freq 1
      pos 707
  term function
    doc 0
      freq 1
      pos 17532
    doc 1
      freq 2
      pos 2040
      pos 9913
    doc 2
      freq 2
      pos 1679
      pos 6710
    doc 3
      freq 7
      pos 971
      pos 1359
      pos 1399
      pos 2139
      pos 2657
      pos 3132
      pos 6262
    doc 4
      freq 4
      pos 1892
      pos 3669
      pos 3835
      pos 6417
    doc 5
      freq 9
      pos 1219
      pos 1235
      pos 1260
      pos 1355
      pos 3929
      pos 3955
      pos 4050
      pos 4058
      pos 4747
    doc 6
      freq 1
      pos 3547
    doc 7
      freq 1
      pos 3252
    doc 8
      freq 1
      pos 2469
    doc 9
      freq 1
      pos 2114
    doc 10
      freq 1
      pos 13775
    doc 11
      freq 1
      pos 10936
    doc 12
      freq 4
      pos 3262
      pos 4120
      pos 4134
      pos 9786
    doc 13
      freq 1
      pos 7401
    doc 14
      freq 1
      pos 5867
    doc 15
      freq 1
      pos 4386
    doc 16
      freq 1
      pos 2997
    doc 17
      freq 1
      pos 2721
    doc 18
      freq 6
      pos 671
      pos 1070
      pos 1340
      pos 1820
      pos 1845
      pos 2509
    skipList 
      level 0
        skipDoc 7
        skipDocFP 981224
        impacts 
          impact 
            freq 1
            norm 100
          impact 
            freq 9
            norm 104
        impactsEnd 
        skipDoc 15
        skipDocFP 981813
        impacts 
          impact 
            freq 1
            norm 95
          impact 
            freq 4
            norm 113
        impactsEnd 
  term functional
    doc 2
      freq 1
      pos 3537
    doc 6
      freq 1
      pos 2887
  term functionality
    doc 0
      freq 1
      pos 379
    doc 1
      freq 2
      pos 3004
      pos 3036
    doc 2
      freq 1
      pos 1422
    doc 3
      freq 2
      pos 1534
      pos 5846
    doc 5
      freq 1
      pos 3254
    doc 13
      freq 1
      pos 3842
    doc 15
      freq 1
      pos 2629
  term functions
    doc 2
      freq 1
      pos 1587
    doc 3
      freq 3
      pos 991
      pos 1014
      pos 1067
    doc 4
      freq 2
      pos 347
      pos 495
    doc 5
      freq 2
      pos 3943
      pos 3966
    doc 7
      freq 1
      pos 1187
    doc 10
      freq 2
      pos 7972
      pos 10470
    doc 12
      freq 1
      pos 6666
    doc 18
      freq 17
      pos 170
      pos 842
      pos 888
      pos 897
      pos 1205
      pos 1230
      pos 1246
      pos 1251
      pos 1371
      pos 1557
      pos 1598
      pos 1716
      pos 1804
      pos 1866
      pos 1888
      pos 1897
      pos 1989
    skipList 
      level 0
        skipDoc 18
        skipDocFP 983210
        impacts 
          impact 
            freq 17
            norm 97
        impactsEnd 
  term fund
    doc 2
      freq 1
      pos 1186
  term funding
    doc 0
      freq 1
      pos 17527
    doc 1
      freq 1
      pos 9908
    doc 2
      freq 1
      pos 6705
    doc 3
      freq 1
      pos 6257
    doc 4
      freq 1
      pos 6412
    doc 5
      freq 1
      pos 4742
    doc 6
      freq 1
      pos 3542
    doc 7
      freq 1
      pos 3247
    doc 8
      freq 1
      pos 2464
    doc 9
      freq 1
      pos 2109
    doc 10
      freq 1
      pos 13770
    doc 11
      freq 1
      pos 10931
    doc 12
      freq 1
      pos 9781
    doc 13
      freq 1
      pos 7396
    doc 14
      freq 1
      pos 5862
    doc 15
      freq 1
      pos 4381
    doc 16
      freq 1
      pos 2992
    doc 17
      freq 1
      pos 2716
    doc 18
      freq 1
      pos 2504
    skipList 
      level 0
        skipDoc 7
        skipDocFP 984059
        impacts 
          impact 
            freq 1
            norm 100
        impactsEnd 
        skipDoc 15
        skipDocFP 984364
        impacts 
          impact 
            freq 1
            norm 95
        impactsEnd 
  term funet
    doc 12
      freq 2
      pos 18
      pos 9457
  term funet.f
    doc 12
      freq 1
      pos 9462
  term funky.example.com
    doc 11
      freq 2
      pos 2695
      pos 2703
  term further
    doc 0
      freq 2
      pos 2031
      pos 2066
    doc 1
      freq 1
      pos 2577
    doc 2
      freq 1
      pos 5801
    doc 3
      freq 2
      pos 5349
      pos 5850
    doc 5
      freq 1
      pos 826
    doc 6
      freq 2
      pos 734
      pos 1690
    doc 7
      freq 2
      pos 193
      pos 457
    doc 10
      freq 4
      pos 3764
      pos 5461
      pos 10981
      pos 11115
    doc 12
      freq 5
      pos 3012
      pos 3122
      pos 5279
      pos 9343
      pos 9389
    doc 13
      freq 2
      pos 560
      pos 2158
    doc 14
      freq 1
      pos 1857
    doc 15
      freq 1
      pos 1011
    doc 16
      freq 1
      pos 987
    doc 17
      freq 1
      pos 1982
    doc 18
      freq 1
      pos 1991
    skipList 
      level 0
        skipDoc 10
        skipDocFP 985310
        impacts 
          impact 
            freq 2
            norm 100
          impact 
            freq 4
            norm 116
        impactsEnd 
  term furthermor
    doc 5
      freq 1
      pos 2806
    doc 6
      freq 1
      pos 478
    doc 10
      freq 3
      pos 566
      pos 4281
      pos 9667
    doc 13
      freq 4
      pos 766
      pos 854
      pos 2402
      pos 6525
    doc 18
      freq 2
      pos 507
      pos 868
  term futur
    doc 0
      freq 11
      pos 12914
      pos 13168
      pos 13270
      pos 13487
      pos 13585
      pos 13677
      pos 13779
      pos 13852
      pos 13936
      pos 14064
      pos 14193
    doc 3
      freq 2
      pos 3553
      pos 3701
    doc 4
      freq 6
      pos 889
      pos 903
      pos 911
      pos 4876
      pos 4896
      pos 4950
    doc 6
      freq 1
      pos 682
    doc 7
      freq 1
      pos 680
    doc 10
      freq 9
      pos 1601
      pos 2234
      pos 5747
      pos 5915
      pos 7764
      pos 9555
      pos 11254
      pos 11318
      pos 11427
    doc 11
      freq 1
      pos 6849
    doc 15
      freq 2
      pos 181
      pos 3691
    skipList 
      level 0
        skipDoc 15
        skipDocFP 986597
        impacts 
          impact 
            freq 1
            norm 100
          impact 
            freq 2
            norm 104
          impact 
            freq 6
            norm 108
          impact 
            freq 9
            norm 116
          impact 
            freq 11
            norm 120
        impactsEnd 
  term fuwd
    doc 11
      freq 1
      pos 10258
  term fvcnyaz
    doc 10
      freq 2
      pos 6561
      pos 6654
  term fvhdk6g4ye7lzfdubzjx5879umv
    doc 11
      freq 1
      pos 10257
  term fvnnw9n
    doc 10
      freq 1
      pos 12631
  term fw7gvxbbarik
    doc 11
      freq 1
      pos 10053
  term fwl9meuhwizo1cejebdy
    doc 11
      freq 1
      pos 3806
  term fwt6
    doc 11
      freq 1
      pos 10498
  term fwvvefp8qyrxm
    doc 10
      freq 1
      pos 12677
  term fxd2lobs
    doc 10
      freq 1
      pos 12566
  term fxqtx34i3gkzazxmn0a66ks9v
    doc 10
      freq 1
      pos 6859
  term fxvibr7sukn3ixiljbr2fkm
    doc 10
      freq 1
      pos 12582
  term fyn1f
    doc 11
      freq 1
      pos 10492
  term fyz4
    doc 10
      freq 1
      pos 12673
  term fzsnel234
    doc 11
      freq 1
      pos 2582
  term g
    doc 1
      freq 6
      pos 30
      pos 8935
      pos 9077
      pos 9106
      pos 9136
      pos 9283
    doc 2
      freq 4
      pos 3048
      pos 3067
      pos 3107
      pos 3166
    doc 3
      freq 4
      pos 25
      pos 4314
      pos 4362
      pos 4752
    doc 5
      freq 1
      pos 4321
    doc 8
      freq 5
      pos 1796
      pos 1966
      pos 1993
      pos 2060
      pos 2103
    doc 9
      freq 1
      pos 1745
    doc 10
      freq 2
      pos 12636
      pos 13096
    doc 11
      freq 1
      pos 9635
    doc 12
      freq 3
      pos 7351
      pos 7473
      pos 7715
    doc 13
      freq 1
      pos 6834
    doc 14
      freq 1
      pos 3
    skipList 
      level 0
        skipDoc 11
        skipDocFP 988548
        impacts 
          impact 
            freq 1
            norm 95
          impact 
            freq 5
            norm 97
          impact 
            freq 6
            norm 113
        impactsEnd 
  term g0sprxm2sy0q2
    doc 10
      freq 1
      pos 12783
  term g1idmdza7zkolvxlmvky
    doc 10
      freq 1
      pos 12543
  term g2wxhgtv1pf7hhul
    doc 11
      freq 1
      pos 3802
  term g8522pzwg7egwspzzwidaqab
    doc 10
      freq 1
      pos 6214
  term ga25hfigw
    doc 10
      freq 1
      pos 6852
  term gain
    doc 15
      freq 1
      pos 1156
  term gaining
    doc 6
      freq 1
      pos 2600
  term games
    doc 13
      freq 1
      pos 3238
  term gaming
    doc 10
      freq 1
      pos 1694
    doc 13
      freq 4
      pos 223
      pos 3236
      pos 3255
      pos 3282
  term ganguly
    doc 0
      freq 1
      pos 15926
  term gap
    doc 0
      freq 11
      pos 12895
      pos 13149
      pos 13251
      pos 13468
      pos 13566
      pos 13658
      pos 13760
      pos 13833
      pos 13905
      pos 14045
      pos 14174
  term gaps
    doc 6
      freq 1
      pos 1621
  term gary
    doc 6
      freq 1
      pos 3134
  term gate
    doc 14
      freq 1
      pos 5511
  term gateway
    doc 6
      freq 1
      pos 2663
    doc 7
      freq 5
      pos 772
      pos 782
      pos 2014
      pos 2162
      pos 2187
  term gathered
    doc 15
      freq 1
      pos 873
  term gautham
    doc 11
      freq 1
      pos 9441
  term gavin
    doc 0
      freq 1
      pos 15948
  term gawibagibadanbgkqhkig9w0baqufadbxmqswcqydvqqgewjvuzel
    doc 10
      freq 1
      pos 6880
  term gb
    doc 14
      freq 2
      pos 5518
      pos 5535
    doc 16
      freq 3
      pos 1337
      pos 1354
      pos 1385
  term gb5zhvqzgj8g2eegilntqoyyvugf3ic3ekvsakm0peuu
    doc 11
      freq 1
      pos 9915
  term gblx.net
    doc 1
      freq 1
      pos 9365
  term gbps
    doc 2
      freq 1
      pos 3969
  term gcrnw
    doc 11
      freq 1
      pos 10183
  term gcwsukqf0uqradk2
    doc 10
      freq 1
      pos 12609
  term gcza
    doc 11
      freq 1
      pos 3805
  term gdhswbpjcvacrxqfk
    doc 11
      freq 1
      pos 10170
  term gdmo
    doc 0
      freq 2
      pos 355
      pos 363
  term ge22dce1sz3p6w2cnrlhyvvf1dzxrizd6jf2fzvd
    doc 11
      freq 1
      pos 10038
  term gen
    doc 1
      freq 1
      pos 3672
    doc 13
      freq 4
      pos 3633
      pos 3672
      pos 3711
      pos 3821
  term general
    doc 0
      freq 1
      pos 17450
    doc 1
      freq 5
      pos 3143
      pos 3447
      pos 5226
      pos 8406
      pos 9831
    doc 2
      freq 2
      pos 1529
      pos 6628
    doc 3
      freq 5
      pos 2911
      pos 2954
      pos 3224
      pos 4078
      pos 6180
    doc 4
      freq 8
      pos 162
      pos 380
      pos 531
      pos 584
      pos 848
      pos 5988
      pos 5995
      pos 6335
    doc 5
      freq 8
      pos 294
      pos 2565
      pos 2569
      pos 2667
      pos 2725
      pos 3735
      pos 3738
      pos 4665
    doc 6
      freq 2
      pos 573
      pos 3465
    doc 7
      freq 1
      pos 3170
    doc 8
      freq 2
      pos 228
      pos 2387
    doc 9
      freq 3
      pos 630
      pos 1240
      pos 2032
    doc 10
      freq 3
      pos 4484
      pos 8281
      pos 13693
    doc 11
      freq 2
      pos 6336
      pos 10854
    doc 12
      freq 4
      pos 1518
      pos 1972
      pos 2746
      pos 9704
    doc 13
      freq 8
      pos 241
      pos 1112
      pos 1998
      pos 3622
      pos 3872
      pos 4980
      pos 5449
      pos 7319
    doc 14
      freq 1
      pos 5785
    doc 15
      freq 6
      pos 170
      pos 462
      pos 862
      pos 1643
      pos 2363
      pos 4304
    doc 16
      freq 1
      pos 2915
    doc 17
      freq 3
      pos 972
      pos 2025
      pos 2639
    doc 18
      freq 1
      pos 2427
    skipList 
      level 0
        skipDoc 7
        skipDocFP 991813
        impacts 
          impact 
            freq 1
            norm 100
          impact 
            freq 2
            norm 101
          impact 
            freq 8
            norm 104
        impactsEnd 
        skipDoc 15
        skipDocFP 992471
        impacts 
          impact 
            freq 3
            norm 95
          impact 
            freq 6
            norm 104
          impact 
            freq 8
            norm 109
        impactsEnd 
  term generalised
    doc 15
      freq 1
      pos 3131
  term generaliz
    doc 13
      freq 1
      pos 485
  term generalization
    doc 13
      freq 1
      pos 580
  term generalized
    doc 1
      freq 23
      pos 256
      pos 268
      pos 2893
      pos 2927
      pos 2976
      pos 2985
      pos 3590
      pos 3619
      pos 3957
      pos 4277
      pos 4298
      pos 4395
      pos 4402
      pos 5285
      pos 5430
      pos 5461
      pos 5530
      pos 5734
      pos 7116
      pos 7206
      pos 7296
      pos 8753
      pos 8796
    doc 3
      freq 1
      pos 3056
  term generalizing
    doc 13
      freq 1
      pos 1159
  term generally
    doc 0
      freq 1
      pos 241
    doc 1
      freq 2
      pos 1574
      pos 4592
    doc 2
      freq 1
      pos 4510
    doc 9
      freq 1
      pos 547
    doc 12
      freq 1
      pos 5660
    doc 13
      freq 4
      pos 950
      pos 1062
      pos 2840
      pos 4631
    doc 14
      freq 1
      pos 1269
  term generat
    doc 0
      freq 6
      pos 2827
      pos 5155
      pos 6567
      pos 13016
      pos 13045
      pos 14106
    doc 9
      freq 2
      pos 463
      pos 722
    doc 10
      freq 3
      pos 2331
      pos 5985
      pos 6106
    doc 11
      freq 2
      pos 1872
      pos 1877
    doc 15
      freq 1
      pos 1908
    doc 17
      freq 1
      pos 1658
    doc 18
      freq 3
      pos 844
      pos 890
      pos 1232
  term generated
    doc 0
      freq 13
      pos 2558
      pos 3380
      pos 3428
      pos 3943
      pos 3974
      pos 12798
      pos 12815
      pos 12837
      pos 12871
      pos 12930
      pos 12952
      pos 13042
      pos 14262
    doc 4
      freq 3
      pos 2233
      pos 2270
      pos 5761
    doc 9
      freq 4
      pos 756
      pos 779
      pos 808
      pos 1073
    doc 10
      freq 6
      pos 4863
      pos 5506
      pos 6465
      pos 7215
      pos 8726
      pos 11037
    doc 12
      freq 4
      pos 3860
      pos 5869
      pos 7548
      pos 7921
    doc 15
      freq 2
      pos 1859
      pos 3646
    doc 18
      freq 11
      pos 588
      pos 795
      pos 859
      pos 875
      pos 925
      pos 1057
      pos 1149
      pos 1156
      pos 1187
      pos 1271
      pos 1615
  term generates
    doc 10
      freq 3
      pos 1820
      pos 6741
      pos 8567
    doc 12
      freq 1
      pos 5946
  term generating
    doc 9
      freq 2
      pos 735
      pos 746
    doc 10
      freq 2
      pos 4207
      pos 5047
    doc 14
      freq 1
      pos 2598
    doc 17
      freq 1
      pos 1422
    doc 18
      freq 1
      pos 117
  term generation
    doc 0
      freq 13
      pos 4839
      pos 5668
      pos 12881
      pos 13135
      pos 13237
      pos 13454
      pos 13552
      pos 13644
      pos 13746
      pos 13819
      pos 13891
      pos 14031
      pos 14160
    doc 5
      freq 1
      pos 761
    doc 7
      freq 1
      pos 2659
    doc 10
      freq 2
      pos 2886
      pos 3356
    doc 12
      freq 1
      pos 7598
    doc 14
      freq 1
      pos 318
    doc 17
      freq 1
      pos 334
    doc 18
      freq 3
      pos 599
      pos 1643
      pos 1687
    skipList 
      level 0
        skipDoc 18
        skipDocFP 996435
        impacts 
          impact 
            freq 3
            norm 97
          impact 
            freq 13
            norm 120
        impactsEnd 
  term generic
    doc 1
      freq 6
      pos 2244
      pos 2260
      pos 2374
      pos 5192
      pos 5741
      pos 7870
    doc 3
      freq 3
      pos 219
      pos 2126
      pos 3275
    doc 6
      freq 1
      pos 700
    doc 10
      freq 1
      pos 4849
    doc 11
      freq 2
      pos 1303
      pos 9687
    doc 12
      freq 4
      pos 1639
      pos 3443
      pos 5225
      pos 5412
    doc 13
      freq 2
      pos 505
      pos 1222
    doc 15
      freq 1
      pos 2802
    skipList 
      level 0
        skipDoc 15
        skipDocFP 997217
        impacts 
          impact 
            freq 1
            norm 101
          impact 
            freq 3
            norm 107
          impact 
            freq 6
            norm 113
        impactsEnd 
  term genre
    doc 13
      freq 1
      pos 1316
  term geoff
    doc 14
      freq 1
      pos 5524
  term geoffrey
    doc 14
      freq 1
      pos 5507
  term georg
    doc 6
      freq 1
      pos 3209
  term gerifp341rmym
    doc 10
      freq 1
      pos 6218
  term germany
    doc 5
      freq 2
      pos 4408
      pos 4422
    doc 15
      freq 1
      pos 4058
  term get
    doc 0
      freq 2
      pos 16787
      pos 16875
    doc 1
      freq 2
      pos 8256
      pos 8467
    doc 2
      freq 3
      pos 752
      pos 2291
      pos 4571
    doc 3
      freq 1
      pos 2987
    doc 4
      freq 1
      pos 4681
    doc 12
      freq 5
      pos 1202
      pos 2918
      pos 4996
      pos 6673
      pos 8056
    doc 13
      freq 1
      pos 4571
    doc 15
      freq 2
      pos 2386
      pos 2451
    doc 16
      freq 1
      pos 453
    skipList 
      level 0
        skipDoc 15
        skipDocFP 998374
        impacts 
          impact 
            freq 2
            norm 104
          impact 
            freq 3
            norm 108
          impact 
            freq 5
            norm 113
        impactsEnd 
  term getaddrinf
    doc 12
      freq 5
      pos 1756
      pos 3261
      pos 3312
      pos 3340
      pos 3850
  term getiee
    doc 2
      freq 2
      pos 756
      pos 2286
  term getieee802
    doc 2
      freq 1
      pos 2298
  term gets
    doc 12
      freq 1
      pos 2912
  term getting
    doc 7
      freq 1
      pos 20
    doc 12
      freq 2
      pos 8292
      pos 8398
    doc 16
      freq 1
      pos 438
  term gettys
    doc 13
      freq 1
      pos 6883
  term gew0yh1xbbxzdz5r8tepvzs8ojlekvmxwkk72kemlzhk
    doc 11
      freq 1
      pos 10437
  term gew4jseocx2ghnqdgmbga3bp8n9l8r
    doc 10
      freq 1
      pos 12683
  term ggcugktp8ad3ykemderj
    doc 10
      freq 1
      pos 12465
  term ghe8k0p
    doc 10
      freq 1
      pos 6892
  term ghhq1bgt9wwsvfhr
    doc 11
      freq 1
      pos 10445
  term ghsdhgdwet
    doc 10
      freq 1
      pos 12486
  term gigabit
    doc 6
      freq 1
      pos 2540
  term giles
    doc 1
      freq 1
      pos 9539
    doc 3
      freq 1
      pos 5904
  term giles.heron
    doc 1
      freq 1
      pos 9555
    doc 3
      freq 1
      pos 5920
  term gilligan
    doc 12
      freq 2
      pos 6767
      pos 7576
  term ginsberg
    doc 0
      freq 1
      pos 15928
  term give
    doc 0
      freq 1
      pos 16859
    doc 12
      freq 1
      pos 553
    doc 15
      freq 3
      pos 1726
      pos 1930
      pos 2947
  term given
    doc 0
      freq 1
      pos 5400
    doc 1
      freq 2
      pos 1691
      pos 8801
    doc 3
      freq 4
      pos 3437
      pos 3454
      pos 3486
      pos 3500
    doc 4
      freq 2
      pos 385
      pos 1217
    doc 5
      freq 1
      pos 1651
    doc 6
      freq 4
      pos 2232
      pos 2298
      pos 2352
      pos 2645
    doc 9
      freq 2
      pos 1208
      pos 1389
    doc 10
      freq 18
      pos 1488
      pos 1664
      pos 1681
      pos 2541
      pos 2764
      pos 2939
      pos 3700
      pos 3746
      pos 3991
      pos 4569
      pos 6029
      pos 6551
      pos 6746
      pos 6794
      pos 7254
      pos 8296
      pos 11196
      pos 11496
    doc 12
      freq 1
      pos 1761
    doc 14
      freq 1
      pos 351
    doc 15
      freq 2
      pos 1963
      pos 3687
    doc 17
      freq 4
      pos 102
      pos 130
      pos 246
      pos 1354
    doc 18
      freq 2
      pos 734
      pos 1782
    skipList 
      level 0
        skipDoc 10
        skipDocFP 1000571
        impacts 
          impact 
            freq 2
            norm 95
          impact 
            freq 4
            norm 101
          impact 
            freq 18
            norm 116
        impactsEnd 
  term gives
    doc 4
      freq 1
      pos 4405
    doc 6
      freq 1
      pos 1575
    doc 11
      freq 1
      pos 78
    doc 12
      freq 1
      pos 583
  term giving
    doc 0
      freq 1
      pos 16834
    doc 15
      freq 1
      pos 1305
  term gkpdhdvdxja5er1y22trxxed
    doc 10
      freq 1
      pos 12495
  term gl94yg7az9fegajur9mrbbzvphzrqsrrpkd8zbfqjnksof2fvvuzrfl2dbtr
    doc 11
      freq 1
      pos 10114
  term glanc
    doc 6
      freq 1
      pos 245
  term glatt
    doc 7
      freq 1
      pos 2903
  term glattzentrum
    doc 7
      freq 1
      pos 2905
  term gln8typfaeyq95tgcvtcwzdoblvpbd
    doc 10
      freq 1
      pos 6908
  term global
    doc 1
      freq 1
      pos 9355
    doc 2
      freq 1
      pos 1583
    doc 4
      freq 1
      pos 2421
    doc 12
      freq 2
      pos 2675
      pos 3435
    doc 13
      freq 1
      pos 5430
    doc 15
      freq 1
      pos 2785
  term globally
    doc 1
      freq 1
      pos 3201
    doc 12
      freq 2
      pos 887
      pos 2780
  term glue
    doc 12
      freq 2
      pos 8207
      pos 8213
  term gmbh
    doc 7
      freq 2
      pos 11
      pos 2902
  term gmt
    doc 10
      freq 6
      pos 6361
      pos 6494
      pos 6646
      pos 7145
      pos 7244
      pos 7358
    doc 11
      freq 5
      pos 3847
      pos 6045
      pos 6121
      pos 6133
      pos 6138
  term go
    doc 4
      freq 1
      pos 4197
    doc 10
      freq 1
      pos 8090
    doc 12
      freq 1
      pos 6730
    doc 13
      freq 1
      pos 2128
  term goal
    doc 12
      freq 1
      pos 6736
    doc 15
      freq 1
      pos 3559
    doc 17
      freq 1
      pos 107
  term goes
    doc 0
      freq 1
      pos 5067
  term going
    doc 7
      freq 1
      pos 1368
    doc 11
      freq 1
      pos 6101
    doc 12
      freq 3
      pos 1850
      pos 6060
      pos 9228
  term gone
    doc 2
      freq 2
      pos 1118
      pos 3933
  term gont
    doc 4
      freq 1
      pos 5440
  term gonzal
    doc 11
      freq 1
      pos 9469
    doc 13
      freq 1
      pos 6962
  term good
    doc 3
      freq 1
      pos 4107
    doc 9
      freq 2
      pos 413
      pos 467
    doc 10
      freq 4
      pos 1733
      pos 9224
      pos 11102
      pos 11441
    doc 12
      freq 1
      pos 4759
    doc 15
      freq 1
      pos 3415
    doc 18
      freq 1
      pos 1862
  term goodspeed
    doc 0
      freq 1
      pos 15930
  term googl
    doc 11
      freq 1
      pos 1174
    doc 13
      freq 1
      pos 2828
  term governed
    doc 10
      freq 1
      pos 722
  term goyret
    doc 2
      freq 1
      pos 3078
    doc 3
      freq 1
      pos 4720
  term graaf
    doc 2
      freq 1
      pos 2918
  term gracefully
    doc 12
      freq 1
      pos 3749
  term grained
    doc 13
      freq 1
      pos 1775
  term grammar
    doc 10
      freq 1
      pos 4789
    doc 11
      freq 2
      pos 2166
      pos 2623
  term grant
    doc 2
      freq 2
      pos 869
      pos 880
  term granted
    doc 10
      freq 1
      pos 11391
  term granularity
    doc 4
      freq 1
      pos 663
  term gratefully
    doc 6
      freq 1
      pos 3090
  term great
    doc 0
      freq 3
      pos 3636
      pos 4152
      pos 10994
    doc 3
      freq 1
      pos 4890
  term greater
    doc 0
      freq 2
      pos 2574
      pos 2835
    doc 1
      freq 1
      pos 8642
    doc 2
      freq 1
      pos 637
    doc 3
      freq 1
      pos 4231
    doc 6
      freq 2
      pos 1623
      pos 2319
    doc 9
      freq 1
      pos 484
    doc 10
      freq 1
      pos 9358
  term greatly
    doc 10
      freq 1
      pos 2745
    doc 18
      freq 1
      pos 1797
  term greek
    doc 18
      freq 1
      pos 907
  term greg
    doc 11
      freq 1
      pos 9584
    doc 15
      freq 1
      pos 3862
  term gross
    doc 0
      freq 1
      pos 15932
  term grounds
    doc 10
      freq 1
      pos 2692
  term group
    doc 0
      freq 24
      pos 2
      pos 1037
      pos 1039
      pos 1087
      pos 1096
      pos 5971
      pos 5981
      pos 5996
      pos 6008
      pos 6033
      pos 6048
      pos 6060
      pos 7892
      pos 9941
      pos 15404
      pos 15477
      pos 15545
      pos 15591
      pos 15622
      pos 15669
      pos 15694
      pos 15736
      pos 15765
      pos 16988
    doc 1
      freq 27
      pos 2
      pos 1697
      pos 2494
      pos 2609
      pos 2626
      pos 2636
      pos 2650
      pos 2703
      pos 2996
      pos 3007
      pos 3219
      pos 3231
      pos 3245
      pos 3256
      pos 3267
      pos 3487
      pos 4133
      pos 4141
      pos 4209
      pos 5396
      pos 5422
      pos 5444
      pos 7099
      pos 7133
      pos 7302
      pos 7341
      pos 7790
    doc 2
      freq 12
      pos 2
      pos 352
      pos 425
      pos 441
      pos 1265
      pos 1629
      pos 1706
      pos 1777
      pos 2026
      pos 2374
      pos 4213
      pos 5680
    doc 3
      freq 2
      pos 2
      pos 4990
    doc 4
      freq 5
      pos 2
      pos 1155
      pos 4851
      pos 5465
      pos 5469
    doc 5
      freq 11
      pos 2
      pos 212
      pos 412
      pos 429
      pos 621
      pos 668
      pos 674
      pos 729
      pos 3070
      pos 3797
      pos 4013
    doc 6
      freq 1
      pos 2
    doc 7
      freq 8
      pos 2
      pos 338
      pos 400
      pos 437
      pos 625
      pos 1152
      pos 1468
      pos 1582
    doc 8
      freq 7
      pos 2
      pos 94
      pos 149
      pos 214
      pos 1317
      pos 1330
      pos 1487
    doc 9
      freq 1
      pos 2
    doc 10
      freq 1
      pos 2
    doc 11
      freq 1
      pos 2
    doc 12
      freq 1
      pos 2
    doc 13
      freq 8
      pos 2
      pos 379
      pos 1175
      pos 1565
      pos 2249
      pos 2411
      pos 4411
      pos 4924
    doc 14
      freq 1
      pos 2
    doc 15
      freq 1
      pos 2
    doc 16
      freq 2
      pos 2
      pos 1585
    doc 17
      freq 2
      pos 2
      pos 1980
    doc 18
      freq 2
      pos 2
      pos 518
    skipList 
      level 0
        skipDoc 7
        skipDocFP 1005797
        impacts 
          impact 
            freq 8
            norm 100
          impact 
            freq 11
            norm 104
          impact 
            freq 12
            norm 108
          impact 
            freq 27
            norm 113
        impactsEnd 
        skipDoc 15
        skipDocFP 1007307
        impacts 
          impact 
            freq 1
            norm 95
          impact 
            freq 7
            norm 97
          impact 
            freq 8
            norm 109
        impactsEnd 
  term grouped
    doc 4
      freq 1
      pos 686
    doc 17
      freq 1
      pos 1329
  term grouping
    doc 0
      freq 1
      pos 15401
    doc 1
      freq 19
      pos 280
      pos 2307
      pos 3019
      pos 3843
      pos 4072
      pos 4113
      pos 4121
      pos 4147
      pos 4170
      pos 4197
      pos 4213
      pos 4306
      pos 5437
      pos 5455
      pos 5554
      pos 7110
      pos 7230
      pos 7287
      pos 7344
    doc 11
      freq 1
      pos 1817
  term groups
    doc 0
      freq 7
      pos 434
      pos 14534
      pos 14545
      pos 14748
      pos 14818
      pos 16548
      pos 17142
    doc 1
      freq 1
      pos 2644
    doc 2
      freq 12
      pos 401
      pos 430
      pos 436
      pos 489
      pos 784
      pos 1410
      pos 1716
      pos 4336
      pos 4454
      pos 4475
      pos 4932
      pos 5359
    doc 4
      freq 1
      pos 4848
    doc 9
      freq 1
      pos 576
    doc 13
      freq 2
      pos 6103
      pos 6159
  term growing
    doc 15
      freq 1
      pos 3274
  term grown
    doc 13
      freq 1
      pos 479
  term gss
    doc 7
      freq 2
      pos 2807
      pos 2829
  term gtyuknjlx8pg43
    doc 11
      freq 1
      pos 10349
  term guarante
    doc 3
      freq 2
      pos 2962
      pos 3730
    doc 5
      freq 2
      pos 371
      pos 3493
    doc 6
      freq 1
      pos 1653
    doc 9
      freq 1
      pos 1205
    doc 10
      freq 2
      pos 8961
      pos 11354
    doc 12
      freq 1
      pos 3354
  term guaranteed
    doc 3
      freq 1
      pos 4037
    doc 6
      freq 1
      pos 2943
  term guaranteeing
    doc 12
      freq 1
      pos 1193
  term guarantees
    doc 12
      freq 1
      pos 3937
  term gudmundsson
    doc 12
      freq 1
      pos 7203
    doc 14
      freq 1
      pos 5348
  term guerin
    doc 6
      freq 1
      pos 2940
  term guidanc
    doc 5
      freq 1
      pos 4104
    doc 10
      freq 1
      pos 3698
    doc 15
      freq 1
      pos 1886
  term guide
    doc 13
      freq 9
      pos 89
      pos 104
      pos 593
      pos 811
      pos 1035
      pos 1217
      pos 2949
      pos 2956
      pos 4358
  term guidelines
    doc 0
      freq 1
      pos 349
    doc 2
      freq 4
      pos 283
      pos 1246
      pos 3180
      pos 3355
    doc 3
      freq 2
      pos 290
      pos 5013
    doc 4
      freq 2
      pos 5312
      pos 5882
    doc 5
      freq 2
      pos 2965
      pos 4147
    doc 8
      freq 1
      pos 1731
    doc 9
      freq 1
      pos 1709
    doc 12
      freq 7
      pos 313
      pos 347
      pos 1137
      pos 1973
      pos 3162
      pos 4138
      pos 7338
    skipList 
      level 0
        skipDoc 12
        skipDocFP 1010736
        impacts 
          impact 
            freq 1
            norm 95
          impact 
            freq 2
            norm 104
          impact 
            freq 4
            norm 108
          impact 
            freq 7
            norm 113
        impactsEnd 
  term guides
    doc 13
      freq 28
      pos 35
      pos 128
      pos 358
      pos 572
      pos 584
      pos 762
      pos 1144
      pos 1465
      pos 1553
      pos 1824
      pos 2176
      pos 2568
      pos 2939
      pos 3306
      pos 3667
      pos 3968
      pos 4303
      pos 4678
      pos 5023
      pos 5385
      pos 5655
      pos 5735
      pos 6014
      pos 6336
      pos 6658
      pos 6874
      pos 6948
      pos 7088
  term gulbrandsen
    doc 12
      freq 1
      pos 7489
    doc 14
      freq 1
      pos 5406
  term gunner
    doc 0
      freq 2
      pos 1167
      pos 15850
  term gupta
    doc 4
      freq 2
      pos 22
      pos 6074
  term gurban
    doc 11
      freq 2
      pos 9436
      pos 9476
  term gvgmtvkmkpk
    doc 11
      freq 1
      pos 10037
  term gw1
    doc 11
      freq 2
      pos 8758
      pos 8848
  term gzhypf7fmf6vleazs
    doc 10
      freq 1
      pos 12552
  term gzip
    doc 10
      freq 1
      pos 12192
    doc 11
      freq 1
      pos 9744
  term h
    doc 0
      freq 4
      pos 10609
      pos 10707
      pos 10791
      pos 11633
    doc 1
      freq 1
      pos 9167
    doc 2
      freq 2
      pos 2804
      pos 3273
    doc 3
      freq 4
      pos 878
      pos 882
      pos 895
      pos 899
    doc 5
      freq 3
      pos 9
      pos 4145
      pos 4319
    doc 6
      freq 1
      pos 3064
    doc 7
      freq 1
      pos 14
    doc 8
      freq 2
      pos 1729
      pos 1748
    doc 10
      freq 4
      pos 13094
      pos 13155
      pos 13314
      pos 13390
    doc 11
      freq 3
      pos 25
      pos 9633
      pos 9659
    doc 13
      freq 5
      pos 25
      pos 6832
      pos 6863
      pos 6865
      pos 6888
    skipList 
      level 0
        skipDoc 8
        skipDocFP 1012595
        impacts 
          impact 
            freq 2
            norm 97
          impact 
            freq 3
            norm 104
          impact 
            freq 4
            norm 107
        impactsEnd 
  term h0zcophs
    doc 10
      freq 1
      pos 12686
  term h2005
    doc 12
      freq 2
      pos 1444
      pos 7713
  term h2x98zyj
    doc 11
      freq 1
      pos 10179
  term h4n5
    doc 11
      freq 1
      pos 5959
  term h4siaedwcemc
    doc 11
      freq 1
      pos 9874
  term h4sicffaz0qca25ld2lkzw50lnrhcgdsw0us5nhz7guswqif2cahfikiiqhft992
    doc 10
      freq 1
      pos 12453
  term h7thiwgc
    doc 11
      freq 1
      pos 9982
  term h7x
    doc 11
      freq 1
      pos 10052
  term ha1w
    doc 11
      freq 1
      pos 10391
  term haberman
    doc 0
      freq 1
      pos 17111
    doc 12
      freq 1
      pos 7413
  term habits
    doc 13
      freq 1
      pos 6037
  term had
    doc 1
      freq 2
      pos 6636
      pos 6665
    doc 2
      freq 4
      pos 1998
      pos 3609
      pos 4455
      pos 5272
    doc 10
      freq 1
      pos 2645
    doc 14
      freq 1
      pos 1289
  term hagin
    doc 4
      freq 1
      pos 5493
    doc 12
      freq 1
      pos 7352
  term hahn
    doc 5
      freq 2
      pos 4402
      pos 4416
  term hain
    doc 12
      freq 1
      pos 7207
  term half
    doc 5
      freq 1
      pos 2233
    doc 12
      freq 1
      pos 4860
  term hallways
    doc 2
      freq 1
      pos 3657
  term halpin
    doc 0
      freq 1
      pos 15934
  term halts
    doc 0
      freq 1
      pos 5666
  term hamilton
    doc 1
      freq 1
      pos 9232
  term hamlin
    doc 1
      freq 1
      pos 9358
  term hampshir
    doc 15
      freq 1
      pos 4028
  term hand
    doc 5
      freq 1
      pos 2167
    doc 9
      freq 1
      pos 299
    doc 10
      freq 1
      pos 12429
    doc 11
      freq 1
      pos 9836
    doc 12
      freq 3
      pos 4385
      pos 6116
      pos 6899
    doc 15
      freq 1
      pos 3186
  term handed
    doc 3
      freq 1
      pos 2308
  term handl
    doc 4
      freq 1
      pos 1519
    doc 11
      freq 1
      pos 3275
    doc 15
      freq 4
      pos 148
      pos 176
      pos 867
      pos 2703
  term handled
    doc 2
      freq 2
      pos 800
      pos 5158
    doc 9
      freq 1
      pos 1040
    doc 11
      freq 1
      pos 712
    doc 14
      freq 1
      pos 2645
    doc 15
      freq 1
      pos 1894
  term handley
    doc 5
      freq 2
      pos 4302
      pos 4328
    doc 10
      freq 1
      pos 13103
    doc 11
      freq 1
      pos 9642
    doc 13
      freq 3
      pos 6758
      pos 6772
      pos 6841
  term handling
    doc 0
      freq 1
      pos 16626
    doc 1
      freq 3
      pos 416
      pos 2574
      pos 9412
    doc 2
      freq 3
      pos 531
      pos 648
      pos 2258
    doc 4
      freq 1
      pos 4075
    doc 10
      freq 3
      pos 272
      pos 2502
      pos 8209
    doc 12
      freq 2
      pos 2890
      pos 7634
    doc 13
      freq 1
      pos 6716
    doc 15
      freq 2
      pos 216
      pos 858
    skipList 
      level 0
        skipDoc 15
        skipDocFP 1016073
        impacts 
          impact 
            freq 2
            norm 104
          impact 
            freq 3
            norm 108
        impactsEnd 
  term handoff
    doc 2
      freq 1
      pos 5970
  term hands
    doc 3
      freq 1
      pos 2132
  term handshak
    doc 0
      freq 5
      pos 442
      pos 6205
      pos 6234
      pos 9168
      pos 17155
    doc 5
      freq 1
      pos 2469
  term hannes
    doc 5
      freq 1
      pos 4412
  term hannes.tschofenig
    doc 5
      freq 1
      pos 4424
  term hans
    doc 0
      freq 1
      pos 15968
    doc 10
      freq 1
      pos 12167
  term happen
    doc 11
      freq 1
      pos 3245
    doc 12
      freq 1
      pos 8099
    doc 16
      freq 1
      pos 1343
  term happens
    doc 0
      freq 1
      pos 13051
    doc 12
      freq 2
      pos 3764
      pos 6614
    doc 15
      freq 2
      pos 1438
      pos 2728
  term harald
    doc 2
      freq 1
      pos 2357
    doc 7
      freq 2
      pos 2918
      pos 2930
  term hardwar
    doc 2
      freq 1
      pos 3847
    doc 3
      freq 1
      pos 3102
    doc 6
      freq 3
      pos 2547
      pos 2589
      pos 2592
  term harmful
    doc 12
      freq 1
      pos 7782
  term harmless
    doc 0
      freq 1
      pos 16643
  term harrington
    doc 0
      freq 1
      pos 17015
    doc 2
      freq 4
      pos 1333
      pos 2828
      pos 3390
      pos 3464
  term harrison
    doc 0
      freq 1
      pos 15936
  term has
    doc 0
      freq 30
      pos 1170
      pos 3096
      pos 5096
      pos 5129
      pos 6146
      pos 6168
      pos 7459
      pos 7486
      pos 7527
      pos 7560
      pos 7915
      pos 7983
      pos 8022
      pos 8075
      pos 8117
      pos 8170
      pos 8201
      pos 8228
      pos 9359
      pos 12146
      pos 12153
      pos 12813
      pos 12860
      pos 12869
      pos 12942
      pos 12950
      pos 14093
      pos 15864
      pos 16681
      pos 17392
    doc 1
      freq 28
      pos 521
      pos 2236
      pos 2811
      pos 2910
      pos 2920
      pos 3463
      pos 3736
      pos 4203
      pos 4365
      pos 4649
      pos 4707
      pos 4726
      pos 4788
      pos 6505
      pos 6517
      pos 6534
      pos 6558
      pos 6598
      pos 6653
      pos 6843
      pos 6883
      pos 6908
      pos 6965
      pos 7063
      pos 7078
      pos 7397
      pos 7542
      pos 9773
    doc 2
      freq 25
      pos 238
      pos 765
      pos 798
      pos 1107
      pos 1111
      pos 1117
      pos 1179
      pos 1322
      pos 1334
      pos 1440
      pos 1665
      pos 1739
      pos 1783
      pos 1959
      pos 1977
      pos 2041
      pos 3886
      pos 3932
      pos 3954
      pos 4654
      pos 4844
      pos 5962
      pos 5992
      pos 6002
      pos 6570
    doc 3
      freq 6
      pos 390
      pos 1317
      pos 2340
      pos 4199
      pos 5394
      pos 6122
    doc 4
      freq 14
      pos 313
      pos 1038
      pos 1069
      pos 1090
      pos 1716
      pos 2413
      pos 2582
      pos 2589
      pos 2662
      pos 5057
      pos 5069
      pos 5093
      pos 5121
      pos 6277
    doc 5
      freq 11
      pos 162
      pos 376
      pos 384
      pos 828
      pos 1466
      pos 2446
      pos 3207
      pos 3818
      pos 3920
      pos 4033
      pos 4607
    doc 6
      freq 5
      pos 145
      pos 300
      pos 770
      pos 2376
      pos 3407
    doc 7
      freq 5
      pos 208
      pos 221
      pos 1407
      pos 1451
      pos 3112
    doc 8
      freq 11
      pos 338
      pos 485
      pos 496
      pos 812
      pos 827
      pos 1141
      pos 1155
      pos 1322
      pos 1336
      pos 1512
      pos 2329
    doc 9
      freq 3
      pos 412
      pos 1521
      pos 1974
    doc 10
      freq 29
      pos 487
      pos 497
      pos 623
      pos 1033
      pos 1231
      pos 1296
      pos 1316
      pos 1327
      pos 1800
      pos 1972
      pos 3323
      pos 3457
      pos 3716
      pos 4078
      pos 5265
      pos 7558
      pos 8156
      pos 8202
      pos 8944
      pos 9532
      pos 10976
      pos 11509
      pos 11609
      pos 11704
      pos 11805
      pos 11899
      pos 11932
      pos 12012
      pos 13635
    doc 11
      freq 26
      pos 1717
      pos 1855
      pos 1920
      pos 2034
      pos 2070
      pos 2083
      pos 2441
      pos 2483
      pos 2647
      pos 2739
      pos 2756
      pos 3239
      pos 3459
      pos 4530
      pos 4999
      pos 5256
      pos 5409
      pos 5557
      pos 6274
      pos 6733
      pos 6804
      pos 6847
      pos 6944
      pos 8778
      pos 8883
      pos 10796
    doc 12
      freq 25
      pos 725
      pos 880
      pos 987
      pos 1827
      pos 1883
      pos 2782
      pos 3192
      pos 3294
      pos 3344
      pos 3727
      pos 3773
      pos 3778
      pos 3886
      pos 3903
      pos 4038
      pos 4886
      pos 5004
      pos 5547
      pos 5760
      pos 6512
      pos 6893
      pos 6925
      pos 8050
      pos 8259
      pos 9646
    doc 13
      freq 13
      pos 478
      pos 595
      pos 793
      pos 1566
      pos 1580
      pos 1728
      pos 1899
      pos 1931
      pos 4232
      pos 4559
      pos 4796
      pos 5944
      pos 7261
    doc 14
      freq 13
      pos 1104
      pos 1197
      pos 1233
      pos 1248
      pos 1750
      pos 2109
      pos 3279
      pos 4312
      pos 4597
      pos 5000
      pos 5017
      pos 5169
      pos 5727
    doc 15
      freq 13
      pos 116
      pos 332
      pos 355
      pos 836
      pos 1517
      pos 1606
      pos 2630
      pos 2886
      pos 3027
      pos 3162
      pos 3502
      pos 3725
      pos 4246
    doc 16
      freq 8
      pos 1302
      pos 1367
      pos 1675
      pos 1721
      pos 1896
      pos 2047
      pos 2465
      pos 2857
    doc 17
      freq 3
      pos 1098
      pos 1388
      pos 2581
    doc 18
      freq 5
      pos 462
      pos 767
      pos 1757
      pos 1937
      pos 2369
    skipList 
      level 0
        skipDoc 7
        skipDocFP 1018056
        impacts 
          impact 
            freq 5
            norm 100
          impact 
            freq 11
            norm 104
          impact 
            freq 25
            norm 108
          impact 
            freq 28
            norm 113
          impact 
            freq 30
            norm 120
        impactsEnd 
        skipDoc 15
        skipDocFP 1020101
        impacts 
          impact 
            freq 3
            norm 95
          impact 
            freq 11
            norm 97
          impact 
            freq 13
            norm 104
          impact 
            freq 25
            norm 113
          impact 
            freq 26
            norm 114
          impact 
            freq 29
            norm 116
        impactsEnd 
  term hash
    doc 5
      freq 4
      pos 1259
      pos 3197
      pos 3668
      pos 3690
    doc 10
      freq 7
      pos 1908
      pos 1925
      pos 4858
      pos 5501
      pos 12238
      pos 12251
      pos 12268
    doc 17
      freq 1
      pos 1666
  term hashed
    doc 10
      freq 2
      pos 4209
      pos 5414
  term hashing
    doc 5
      freq 1
      pos 1354
    doc 10
      freq 2
      pos 2301
      pos 5424
  term haskin
    doc 0
      freq 1
      pos 15938
    doc 4
      freq 1
      pos 5487
  term havard
    doc 12
      freq 1
      pos 6768
  term have
    doc 0
      freq 18
      pos 680
      pos 2271
      pos 3646
      pos 4162
      pos 5086
      pos 5124
      pos 7715
      pos 7730
      pos 8381
      pos 10947
      pos 11004
      pos 11997
      pos 12964
      pos 16078
      pos 16103
      pos 16153
      pos 16577
      pos 16870
    doc 1
      freq 9
      pos 2402
      pos 2883
      pos 3989
      pos 4344
      pos 4352
      pos 6000
      pos 6313
      pos 8577
      pos 8855
    doc 2
      freq 15
      pos 67
      pos 94
      pos 216
      pos 311
      pos 407
      pos 431
      pos 786
      pos 865
      pos 1688
      pos 2105
      pos 2199
      pos 4601
      pos 4823
      pos 4873
      pos 4940
    doc 3
      freq 8
      pos 658
      pos 1170
      pos 1969
      pos 2553
      pos 2573
      pos 2683
      pos 3530
      pos 5613
    doc 4
      freq 6
      pos 581
      pos 718
      pos 727
      pos 1572
      pos 4837
      pos 5614
    doc 5
      freq 2
      pos 804
      pos 886
    doc 7
      freq 4
      pos 229
      pos 1276
      pos 1735
      pos 1769
    doc 8
      freq 2
      pos 82
      pos 1702
    doc 9
      freq 1
      pos 602
    doc 10
      freq 19
      pos 602
      pos 629
      pos 1217
      pos 2018
      pos 2181
      pos 2190
      pos 3677
      pos 3942
      pos 4030
      pos 6123
      pos 6802
      pos 7067
      pos 7941
      pos 9675
      pos 10134
      pos 10436
      pos 10446
      pos 10945
      pos 13035
    doc 11
      freq 7
      pos 699
      pos 705
      pos 991
      pos 1815
      pos 2060
      pos 2802
      pos 7080
    doc 12
      freq 35
      pos 140
      pos 654
      pos 1039
      pos 1184
      pos 1189
      pos 1196
      pos 1281
      pos 1312
      pos 1495
      pos 1631
      pos 1687
      pos 1911
      pos 2342
      pos 2636
      pos 2674
      pos 2703
      pos 2870
      pos 2878
      pos 3610
      pos 4675
      pos 4943
      pos 5615
      pos 5634
      pos 6131
      pos 6142
      pos 6367
      pos 6547
      pos 6683
      pos 6849
      pos 7904
      pos 7930
      pos 8472
      pos 8531
      pos 8935
      pos 8956
    doc 13
      freq 7
      pos 392
      pos 420
      pos 441
      pos 463
      pos 2269
      pos 2657
      pos 4038
    doc 14
      freq 6
      pos 631
      pos 1347
      pos 2147
      pos 2455
      pos 2530
      pos 4442
    doc 15
      freq 15
      pos 76
      pos 824
      pos 1208
      pos 1501
      pos 1704
      pos 1869
      pos 1898
      pos 2098
      pos 2173
      pos 2184
      pos 2661
      pos 2967
      pos 3619
      pos 3642
      pos 3682
    doc 16
      freq 4
      pos 347
      pos 363
      pos 2475
      pos 2486
    doc 17
      freq 3
      pos 961
      pos 1149
      pos 1806
    doc 18
      freq 5
      pos 280
      pos 801
      pos 811
      pos 1153
      pos 1662
    skipList 
      level 0
        skipDoc 8
        skipDocFP 1024027
        impacts 
          impact 
            freq 2
            norm 97
          impact 
            freq 4
            norm 100
          impact 
            freq 8
            norm 107
          impact 
            freq 15
            norm 108
          impact 
            freq 18
            norm 120
        impactsEnd 
        skipDoc 16
        skipDocFP 1025162
        impacts 
          impact 
            freq 1
            norm 95
          impact 
            freq 4
            norm 99
          impact 
            freq 15
            norm 104
          impact 
            freq 35
            norm 113
        impactsEnd 
  term having
    doc 2
      freq 1
      pos 1625
    doc 12
      freq 4
      pos 1344
      pos 3199
      pos 3374
      pos 9366
    doc 13
      freq 1
      pos 2621
    doc 15
      freq 2
      pos 1647
      pos 2260
    doc 16
      freq 4
      pos 148
      pos 215
      pos 399
      pos 893
  term hawrylyshen
    doc 10
      freq 1
      pos 13383
    doc 11
      freq 2
      pos 15
      pos 10536
  term hbrr85
    doc 11
      freq 1
      pos 10468
  term hcolon
    doc 10
      freq 2
      pos 4805
      pos 4819
  term hdlc
    doc 1
      freq 1
      pos 9087
    doc 8
      freq 2
      pos 659
      pos 1976
  term he
    doc 0
      freq 1
      pos 17277
    doc 1
      freq 1
      pos 9658
    doc 2
      freq 2
      pos 4442
      pos 6455
    doc 3
      freq 1
      pos 6007
    doc 4
      freq 1
      pos 6162
    doc 5
      freq 2
      pos 3573
      pos 4492
    doc 6
      freq 1
      pos 3292
    doc 7
      freq 1
      pos 2997
    doc 8
      freq 2
      pos 458
      pos 2214
    doc 9
      freq 1
      pos 1859
    doc 10
      freq 7
      pos 2015
      pos 6717
      pos 6726
      pos 6939
      pos 6947
      pos 9340
      pos 13520
    doc 11
      freq 1
      pos 10681
    doc 12
      freq 2
      pos 5143
      pos 9531
    doc 13
      freq 1
      pos 7146
    doc 14
      freq 1
      pos 5612
    doc 15
      freq 1
      pos 4131
    doc 16
      freq 1
      pos 2742
    doc 17
      freq 1
      pos 2466
    doc 18
      freq 1
      pos 2254
    skipList 
      level 0
        skipDoc 7
        skipDocFP 1028286
        impacts 
          impact 
            freq 1
            norm 100
          impact 
            freq 2
            norm 104
        impactsEnd 
        skipDoc 15
        skipDocFP 1028621
        impacts 
          impact 
            freq 1
            norm 95
          impact 
            freq 2
            norm 97
          impact 
            freq 7
            norm 116
        impactsEnd 
  term header
    doc 0
      freq 9
      pos 1960
      pos 12710
      pos 13114
      pos 13216
      pos 13433
      pos 13519
      pos 13623
      pos 13713
      pos 14342
    doc 1
      freq 5
      pos 468
      pos 552
      pos 644
      pos 1249
      pos 1724
    doc 3
      freq 2
      pos 1612
      pos 3800
    doc 4
      freq 34
      pos 317
      pos 541
      pos 551
      pos 557
      pos 565
      pos 682
      pos 1082
      pos 1286
      pos 1289
      pos 1299
      pos 1305
      pos 1313
      pos 1603
      pos 3317
      pos 3323
      pos 3392
      pos 3464
      pos 3496
      pos 3500
      pos 3509
      pos 4040
      pos 4048
      pos 4067
      pos 4221
      pos 4229
      pos 4234
      pos 4255
      pos 4278
      pos 4293
      pos 4307
      pos 4320
      pos 4757
      pos 5388
      pos 5836
    doc 6
      freq 1
      pos 2827
    doc 10
      freq 211
      pos 141
      pos 225
      pos 310
      pos 318
      pos 341
      pos 478
      pos 495
      pos 837
      pos 1030
      pos 1055
      pos 1110
      pos 1165
      pos 1190
      pos 1241
      pos 1325
      pos 1475
      pos 1486
      pos 1566
      pos 1569
      pos 1830
      pos 1878
      pos 1916
      pos 1943
      pos 1951
      pos 1994
      pos 2002
      pos 2034
      pos 2053
      pos 2066
      pos 2248
      pos 2268
      pos 2280
      pos 2334
      pos 2363
      pos 2493
      pos 2507
      pos 2604
      pos 2730
      pos 2773
      pos 2783
      pos 2895
      pos 2924
      pos 2944
      pos 2975
      pos 3006
      pos 3023
      pos 3045
      pos 3151
      pos 3189
      pos 3231
      pos 3243
      pos 3272
      pos 3292
      pos 3312
      pos 3322
      pos 3338
      pos 3342
      pos 3531
      pos 3539
      pos 3551
      pos 3567
      pos 3592
      pos 3619
      pos 3636
      pos 3647
      pos 3730
      pos 3750
      pos 3759
      pos 3817
      pos 3858
      pos 3892
      pos 3996
      pos 4027
      pos 4051
      pos 4176
      pos 4201
      pos 4239
      pos 4289
      pos 4308
      pos 4426
      pos 4455
      pos 4496
      pos 4651
      pos 4657
      pos 4735
      pos 4758
      pos 4763
      pos 4923
      pos 4953
      pos 4972
      pos 4985
      pos 5000
      pos 5020
      pos 5054
      pos 5161
      pos 5170
      pos 5181
      pos 5354
      pos 5367
      pos 5381
      pos 5387
      pos 5438
      pos 5447
      pos 5552
      pos 5573
      pos 5608
      pos 5727
      pos 5743
      pos 5756
      pos 5783
      pos 5813
      pos 5890
      pos 5933
      pos 5955
      pos 6034
      pos 6427
      pos 6451
      pos 6574
      pos 6734
      pos 6766
      pos 6788
      pos 7031
      pos 7057
      pos 7070
      pos 7079
      pos 7092
      pos 7163
      pos 7292
      pos 7496
      pos 7542
      pos 7553
      pos 7610
      pos 7641
      pos 7705
      pos 7814
      pos 7852
      pos 7890
      pos 7976
      pos 7992
      pos 8002
      pos 8012
      pos 8055
      pos 8066
      pos 8073
      pos 8097
      pos 8162
      pos 8171
      pos 8182
      pos 8233
      pos 8244
      pos 8270
      pos 8328
      pos 8337
      pos 8348
      pos 8369
      pos 8386
      pos 8402
      pos 8422
      pos 8504
      pos 8513
      pos 8540
      pos 8601
      pos 8624
      pos 8645
      pos 8691
      pos 8710
      pos 8718
      pos 8740
      pos 8747
      pos 8796
      pos 8801
      pos 8836
      pos 8854
      pos 8861
      pos 8897
      pos 8920
      pos 9027
      pos 9380
      pos 9414
      pos 9579
      pos 9725
      pos 9734
      pos 10123
      pos 10190
      pos 10216
      pos 10322
      pos 10378
      pos 10391
      pos 10412
      pos 10816
      pos 10825
      pos 11018
      pos 11036
      pos 11085
      pos 11451
      pos 11477
      pos 11479
      pos 11514
      pos 11523
      pos 11529
      pos 11552
      pos 11583
      pos 11598
      pos 11635
      pos 11664
      pos 11769
      pos 11847
      pos 11925
      pos 11970
      pos 11995
      pos 12053
    doc 11
      freq 91
      pos 201
      pos 250
      pos 333
      pos 403
      pos 427
      pos 468
      pos 483
      pos 513
      pos 950
      pos 958
      pos 967
      pos 983
      pos 1006
      pos 1061
      pos 1065
      pos 1077
      pos 1167
      pos 1230
      pos 1243
      pos 1271
      pos 1281
      pos 1286
      pos 1307
      pos 1312
      pos 1323
      pos 1334
      pos 1361
      pos 1368
      pos 1389
      pos 1417
      pos 1423
      pos 1430
      pos 1669
      pos 1693
      pos 1720
      pos 1758
      pos 1833
      pos 1837
      pos 1888
      pos 2466
      pos 2486
      pos 2498
      pos 2643
      pos 2712
      pos 2719
      pos 2737
      pos 2754
      pos 2758
      pos 3566
      pos 3602
      pos 4222
      pos 4227
      pos 4243
      pos 4599
      pos 4750
      pos 4958
      pos 5920
      pos 6034
      pos 6052
      pos 6075
      pos 6106
      pos 6272
      pos 6277
      pos 6398
      pos 6509
      pos 6746
      pos 7168
      pos 7179
      pos 7331
      pos 7352
      pos 7368
      pos 7559
      pos 7572
      pos 7619
      pos 7706
      pos 7718
      pos 7902
      pos 7943
      pos 7965
      pos 8241
      pos 8376
      pos 8388
      pos 8562
      pos 8653
      pos 8873
      pos 8886
      pos 8903
      pos 8989
      pos 9034
      pos 9188
      pos 9239
    doc 16
      freq 4
      pos 488
      pos 1787
      pos 1886
      pos 2168
    skipList 
      level 0
        skipDoc 16
        skipDocFP 1029662
        impacts 
          impact 
            freq 4
            norm 99
          impact 
            freq 34
            norm 108
          impact 
            freq 91
            norm 114
          impact 
            freq 211
            norm 116
        impactsEnd 
  term headers
    doc 0
      freq 2
      pos 901
      pos 11724
    doc 3
      freq 1
      pos 2892
    doc 4
      freq 5
      pos 548
      pos 1568
      pos 3395
      pos 5321
      pos 5891
    doc 6
      freq 2
      pos 2834
      pos 2837
    doc 7
      freq 3
      pos 1007
      pos 1962
      pos 2494
    doc 10
      freq 31
      pos 1912
      pos 2822
      pos 3361
      pos 4256
      pos 4563
      pos 4771
      pos 4779
      pos 4793
      pos 5249
      pos 5294
      pos 5997
      pos 6598
      pos 6751
      pos 6797
      pos 7314
      pos 8256
      pos 8290
      pos 8302
      pos 8476
      pos 9156
      pos 9256
      pos 9265
      pos 9891
      pos 11172
      pos 11263
      pos 11377
      pos 11438
      pos 11488
      pos 11501
      pos 11940
      pos 12292
    doc 11
      freq 5
      pos 322
      pos 5842
      pos 5858
      pos 5889
      pos 5898
  term heard
    doc 0
      freq 1
      pos 15941
    doc 2
      freq 3
      pos 3246
      pos 3352
      pos 3476
  term hearty
    doc 11
      freq 1
      pos 9575
  term heavily
    doc 10
      freq 1
      pos 9972
  term heed
    doc 4
      freq 1
      pos 1865
  term held
    doc 0
      freq 1
      pos 15854
    doc 2
      freq 1
      pos 5663
  term hellman
    doc 5
      freq 3
      pos 796
      pos 822
      pos 4247
  term hello
    doc 0
      freq 11
      pos 758
      pos 6820
      pos 6947
      pos 7863
      pos 8454
      pos 8522
      pos 8559
      pos 8579
      pos 13607
      pos 13697
      pos 13800
    doc 11
      freq 1
      pos 3865
  term hellos
    doc 0
      freq 6
      pos 6092
      pos 6100
      pos 6122
      pos 6813
      pos 6874
      pos 8433
  term hellotimer
    doc 0
      freq 1
      pos 6797
  term help
    doc 0
      freq 8
      pos 2919
      pos 13120
      pos 13222
      pos 13314
      pos 13439
      pos 13525
      pos 13629
      pos 13719
    doc 2
      freq 3
      pos 1718
      pos 2032
      pos 6023
    doc 10
      freq 2
      pos 998
      pos 2293
    doc 12
      freq 1
      pos 4629
    doc 13
      freq 1
      pos 4263
  term helped
    doc 12
      freq 1
      pos 6787
  term helpful
    doc 2
      freq 1
      pos 1964
  term helps
    doc 10
      freq 1
      pos 8451
  term helsink
    doc 13
      freq 2
      pos 21
      pos 7041
  term hemant
    doc 11
      freq 1
      pos 9564
  term hence
    doc 3
      freq 1
      pos 685
    doc 12
      freq 1
      pos 2110
    doc 13
      freq 1
      pos 703
  term henning
    doc 11
      freq 1
      pos 10585
    doc 13
      freq 1
      pos 7057
  term henry
    doc 10
      freq 1
      pos 12119
    doc 11
      freq 1
      pos 9566
  term her
    doc 10
      freq 4
      pos 1825
      pos 1848
      pos 1901
      pos 6429
    doc 13
      freq 1
      pos 1013
  term here
    doc 3
      freq 4
      pos 1085
      pos 3241
      pos 4163
      pos 5851
    doc 5
      freq 4
      pos 418
      pos 1562
      pos 2261
      pos 2269
    doc 6
      freq 1
      pos 1225
    doc 7
      freq 1
      pos 682
    doc 8
      freq 1
      pos 225
    doc 10
      freq 9
      pos 2371
      pos 3703
      pos 3923
      pos 4899
      pos 4928
      pos 5119
      pos 5923
      pos 6093
      pos 12859
    doc 11
      freq 5
      pos 1020
      pos 1108
      pos 1178
      pos 8070
      pos 8368
    doc 12
      freq 6
      pos 899
      pos 1251
      pos 3523
      pos 5281
      pos 6759
      pos 7988
    doc 14
      freq 1
      pos 414
    doc 15
      freq 5
      pos 502
      pos 849
      pos 1402
      pos 1495
      pos 1762
    doc 16
      freq 1
      pos 1428
    doc 18
      freq 3
      pos 419
      pos 956
      pos 1969
    skipList 
      level 0
        skipDoc 12
        skipDocFP 1038451
        impacts 
          impact 
            freq 1
            norm 97
          impact 
            freq 4
            norm 104
          impact 
            freq 6
            norm 113
          impact 
            freq 9
            norm 116
        impactsEnd 
  term herein
    doc 0
      freq 2
      pos 17264
      pos 17314
    doc 1
      freq 5
      pos 846
      pos 1878
      pos 1941
      pos 9645
      pos 9695
    doc 2
      freq 2
      pos 6442
      pos 6492
    doc 3
      freq 3
      pos 670
      pos 5994
      pos 6044
    doc 4
      freq 2
      pos 6149
      pos 6199
    doc 5
      freq 2
      pos 4479
      pos 4529
    doc 6
      freq 2
      pos 3279
      pos 3329
    doc 7
      freq 2
      pos 2984
      pos 3034
    doc 8
      freq 3
      pos 1719
      pos 2201
      pos 2251
    doc 9
      freq 2
      pos 1846
      pos 1896
    doc 10
      freq 2
      pos 13507
      pos 13557
    doc 11
      freq 2
      pos 10668
      pos 10718
    doc 12
      freq 2
      pos 9518
      pos 9568
    doc 13
      freq 2
      pos 7133
      pos 7183
    doc 14
      freq 2
      pos 5599
      pos 5649
    doc 15
      freq 2
      pos 4118
      pos 4168
    doc 16
      freq 2
      pos 2729
      pos 2779
    doc 17
      freq 2
      pos 2453
      pos 2503
    doc 18
      freq 2
      pos 2241
      pos 2291
    skipList 
      level 0
        skipDoc 7
        skipDocFP 1039696
        impacts 
          impact 
            freq 2
            norm 100
          impact 
            freq 3
            norm 107
          impact 
            freq 5
            norm 113
        impactsEnd 
        skipDoc 15
        skipDocFP 1040180
        impacts 
          impact 
            freq 2
            norm 95
          impact 
            freq 3
            norm 97
        impactsEnd 
  term heron
    doc 1
      freq 4
      pos 31
      pos 9076
      pos 9107
      pos 9540
    doc 3
      freq 3
      pos 26
      pos 4361
      pos 5905
    doc 8
      freq 3
      pos 1797
      pos 1965
      pos 1994
  term herzog
    doc 6
      freq 1
      pos 2876
  term heterogeneous
    doc 3
      freq 1
      pos 1527
  term heuristics
    doc 12
      freq 1
      pos 3404
    doc 15
      freq 1
      pos 2914
  term hex
    doc 11
      freq 32
      pos 1030
      pos 1068
      pos 1070
      pos 1084
      pos 1086
      pos 1117
      pos 1156
      pos 1158
      pos 1944
      pos 1946
      pos 1948
      pos 1950
      pos 1952
      pos 1954
      pos 1973
      pos 1975
      pos 1995
      pos 1997
      pos 2013
      pos 2014
      pos 2136
      pos 2137
      pos 2161
      pos 2162
      pos 3890
      pos 3913
      pos 4002
      pos 4007
      pos 4130
      pos 4132
      pos 5790
      pos 5792
  term hexadecimal
    doc 10
      freq 1
      pos 12243
    doc 11
      freq 1
      pos 1025
    doc 12
      freq 1
      pos 1390
  term hgs
    doc 11
      freq 1
      pos 10608
  term hhhgf2qewvafdfaq
    doc 11
      freq 1
      pos 9927
  term hierarchical
    doc 13
      freq 1
      pos 2235
  term hierarchy
    doc 1
      freq 2
      pos 599
      pos 9145
    doc 2
      freq 1
      pos 5985
  term higginson
    doc 0
      freq 1
      pos 15943
  term high
    doc 1
      freq 2
      pos 674
      pos 9548
    doc 3
      freq 1
      pos 5913
    doc 4
      freq 2
      pos 706
      pos 2010
    doc 5
      freq 1
      pos 3599
    doc 6
      freq 3
      pos 2357
      pos 2374
      pos 2415
    doc 7
      freq 1
      pos 2079
    doc 10
      freq 1
      pos 1784
    doc 11
      freq 1
      pos 6653
    doc 12
      freq 1
      pos 3041
    doc 13
      freq 1
      pos 4311
    skipList 
      level 0
        skipDoc 11
        skipDocFP 1042706
        impacts 
          impact 
            freq 1
            norm 100
          impact 
            freq 3
            norm 101
        impactsEnd 
  term higher
    doc 0
      freq 1
      pos 13369
    doc 2
      freq 1
      pos 3724
    doc 5
      freq 1
      pos 3156
    doc 6
      freq 1
      pos 2681
    doc 9
      freq 1
      pos 481
  term highest
    doc 4
      freq 1
      pos 1720
  term highlights
    doc 15
      freq 1
      pos 3041
  term highly
    doc 6
      freq 1
      pos 81
  term hijack
    doc 0
      freq 2
      pos 16237
      pos 16573
  term himanshu
    doc 1
      freq 1
      pos 8886
  term himself
    doc 5
      freq 1
      pos 1468
  term hinden
    doc 2
      freq 1
      pos 6359
    doc 4
      freq 4
      pos 5181
      pos 5330
      pos 5489
      pos 5515
    doc 12
      freq 2
      pos 7409
      pos 7424
  term hint
    doc 0
      freq 7
      pos 1605
      pos 1704
      pos 1749
      pos 1800
      pos 1997
      pos 2024
      pos 2059
    doc 6
      freq 1
      pos 1577
    doc 12
      freq 3
      pos 1760
      pos 3315
      pos 8726
    doc 15
      freq 1
      pos 748
  term hinted
    doc 15
      freq 1
      pos 2309
  term hints
    doc 2
      freq 1
      pos 2312
    doc 12
      freq 2
      pos 978
      pos 4971
  term hiopsxfc2im86mmfiktmlqunifwghm9rnf6r
    doc 10
      freq 1
      pos 12655
  term his
    doc 5
      freq 1
      pos 2370
    doc 10
      freq 2
      pos 7033
      pos 9397
  term historic
    doc 7
      freq 7
      pos 111
      pos 238
      pos 269
      pos 280
      pos 433
      pos 1145
      pos 1599
  term historical
    doc 0
      freq 1
      pos 9027
    doc 10
      freq 1
      pos 12861
  term history
    doc 2
      freq 4
      pos 111
      pos 168
      pos 329
      pos 3497
    doc 7
      freq 3
      pos 118
      pos 158
      pos 214
  term hitos
    doc 13
      freq 1
      pos 6960
  term hkx6is6axxicgmyujmvxjxmdtk
    doc 10
      freq 1
      pos 12779
  term hlp6r
    doc 10
      freq 1
      pos 12728
  term hmac
    doc 5
      freq 7
      pos 1262
      pos 1357
      pos 2103
      pos 2125
      pos 4052
      pos 4060
      pos 4244
  term hmtyns7ltrg9dlxkwz
    doc 10
      freq 2
      pos 7279
      pos 7369
  term hoc
    doc 2
      freq 1
      pos 1776
  term hocbgs5rpsa18ez
    doc 11
      freq 1
      pos 9983
  term hoffman
    doc 10
      freq 1
      pos 13258
  term hold
    doc 4
      freq 1
      pos 2331
    doc 10
      freq 3
      pos 2185
      pos 12917
      pos 12938
    doc 15
      freq 1
      pos 1979
  term holder
    doc 10
      freq 1
      pos 1956
    doc 17
      freq 4
      pos 1538
      pos 1618
      pos 1643
      pos 1705
  term holder's
    doc 17
      freq 2
      pos 1697
      pos 1748
  term holding
    doc 0
      freq 2
      pos 6809
      pos 9260
  term holdingtimer
    doc 0
      freq 1
      pos 9283
  term holdreg
    doc 2
      freq 1
      pos 3074
  term holds
    doc 0
      freq 14
      pos 530
      pos 575
      pos 919
      pos 9354
      pos 12394
      pos 12422
      pos 12447
      pos 12485
      pos 12511
      pos 12541
      pos 12585
      pos 14274
      pos 14287
      pos 14329
    doc 4
      freq 1
      pos 3505
    doc 10
      freq 1
      pos 8102
  term holger
    doc 1
      freq 1
      pos 9302
  term holiday
    doc 16
      freq 1
      pos 2014
  term hollinger
    doc 15
      freq 1
      pos 3860
  term home
    doc 9
      freq 6
      pos 197
      pos 223
      pos 285
      pos 493
      pos 748
      pos 803
    doc 10
      freq 1
      pos 1802
  term homogeneous
    doc 3
      freq 1
      pos 1509
    doc 13
      freq 1
      pos 5222
  term hong
    doc 12
      freq 1
      pos 7349
  term hop
    doc 0
      freq 5
      pos 1717
      pos 10454
      pos 11259
      pos 11293
      pos 11324
    doc 1
      freq 2
      pos 891
      pos 1390
    doc 4
      freq 5
      pos 2854
      pos 3080
      pos 3122
      pos 3133
      pos 3169
    doc 10
      freq 7
      pos 1496
      pos 1498
      pos 4393
      pos 4395
      pos 5867
      pos 5869
      pos 8999
    doc 11
      freq 1
      pos 7364
  term hopps
    doc 0
      freq 1
      pos 15945
    doc 3
      freq 1
      pos 4682
  term hops
    doc 10
      freq 1
      pos 8965
    doc 11
      freq 1
      pos 8581
  term host
    doc 0
      freq 4
      pos 3742
      pos 4268
      pos 10941
      pos 11128
    doc 4
      freq 2
      pos 2016
      pos 4738
    doc 10
      freq 11
      pos 2045
      pos 7881
      pos 8885
      pos 8935
      pos 8942
      pos 10510
      pos 10519
      pos 10543
      pos 10550
      pos 10652
      pos 10670
    doc 11
      freq 1
      pos 5967
    doc 12
      freq 15
      pos 3912
      pos 3974
      pos 3999
      pos 4585
      pos 4587
      pos 4659
      pos 5610
      pos 6074
      pos 6097
      pos 6125
      pos 7186
      pos 7288
      pos 7303
      pos 7443
      pos 9160
    doc 13
      freq 4
      pos 857
      pos 3471
      pos 3474
      pos 4928
    doc 15
      freq 14
      pos 26
      pos 102
      pos 319
      pos 471
      pos 809
      pos 2186
      pos 2206
      pos 2471
      pos 2547
      pos 3475
      pos 3902
      pos 3952
      pos 3967
      pos 3990
  term host.example.com
    doc 11
      freq 6
      pos 2579
      pos 3136
      pos 3349
      pos 6181
      pos 6790
      pos 7653
  term host.example.net
    doc 11
      freq 2
      pos 6880
      pos 6885
  term host1
    doc 11
      freq 7
      pos 1936
      pos 2593
      pos 5491
      pos 5645
      pos 5651
      pos 5797
      pos 8624
  term host105
    doc 11
      freq 2
      pos 4161
      pos 6999
  term host129
    doc 11
      freq 3
      pos 4909
      pos 4939
      pos 5030
  term host15
    doc 11
      freq 1
      pos 9074
  term host198
    doc 11
      freq 1
      pos 4042
  term host2
    doc 11
      freq 2
      pos 2492
      pos 2598
  term host25
    doc 11
      freq 1
      pos 8129
  term host28
    doc 11
      freq 1
      pos 8511
  term host3
    doc 11
      freq 1
      pos 2602
  term host36
    doc 11
      freq 1
      pos 8179
  term host39923
    doc 11
      freq 1
      pos 5949
  term host4
    doc 11
      freq 1
      pos 6443
  term host5
    doc 11
      freq 12
      pos 2226
      pos 2236
      pos 2387
      pos 2394
      pos 2400
      pos 3159
      pos 4477
      pos 5343
      pos 6195
      pos 7853
      pos 8324
      pos 8940
  term host59
    doc 11
      freq 1
      pos 5175
  term host9
    doc 11
      freq 2
      pos 7402
      pos 7533
  term hosting
    doc 10
      freq 3
      pos 10452
      pos 10722
      pos 10737
  term hostnam
    doc 0
      freq 2
      pos 577
      pos 4594
    doc 10
      freq 4
      pos 2184
      pos 2394
      pos 10799
      pos 10842
    doc 12
      freq 6
      pos 2014
      pos 2265
      pos 4596
      pos 4637
      pos 4718
      pos 4740
  term hostnames
    doc 0
      freq 2
      pos 4439
      pos 4469
    doc 12
      freq 1
      pos 2124
  term hosts
    doc 0
      freq 1
      pos 10906
    doc 4
      freq 1
      pos 5257
    doc 12
      freq 3
      pos 4915
      pos 5466
      pos 7582
    doc 13
      freq 5
      pos 959
      pos 1725
      pos 3334
      pos 4130
      pos 5001
    doc 15
      freq 3
      pos 2407
      pos 2424
      pos 2718
  term hour
    doc 9
      freq 1
      pos 1338
    doc 10
      freq 1
      pos 5719
  term hour.example.com
    doc 11
      freq 1
      pos 5970
  term hours
    doc 9
      freq 1
      pos 1340
  term housley
    doc 2
      freq 3
      pos 2137
      pos 2323
      pos 2324
    doc 5
      freq 1
      pos 4093
    doc 9
      freq 1
      pos 1708
    doc 10
      freq 3
      pos 13201
      pos 13227
      pos 13254
    doc 17
      freq 2
      pos 2047
      pos 2078
  term how
    doc 0
      freq 4
      pos 6142
      pos 7053
      pos 7064
      pos 9185
    doc 1
      freq 7
      pos 445
      pos 777
      pos 796
      pos 3303
      pos 4453
      pos 8372
      pos 8396
    doc 2
      freq 2
      pos 1347
      pos 5065
    doc 3
      freq 2
      pos 1178
      pos 2239
    doc 6
      freq 2
      pos 1338
      pos 1469
    doc 7
      freq 3
      pos 321
      pos 1125
      pos 2784
    doc 10
      freq 6
      pos 1180
      pos 1333
      pos 2009
      pos 2265
      pos 3162
      pos 11211
    doc 11
      freq 2
      pos 7335
      pos 8361
    doc 12
      freq 10
      pos 95
      pos 588
      pos 598
      pos 615
      pos 640
      pos 4213
      pos 4444
      pos 4897
      pos 6057
      pos 6727
    doc 13
      freq 2
      pos 1096
      pos 6677
    doc 15
      freq 5
      pos 146
      pos 173
      pos 865
      pos 1890
      pos 3421
    doc 16
      freq 4
      pos 1747
      pos 1868
      pos 2126
      pos 2288
    doc 18
      freq 1
      pos 96
    skipList 
      level 0
        skipDoc 11
        skipDocFP 1051224
        impacts 
          impact 
            freq 3
            norm 100
          impact 
            freq 7
            norm 113
        impactsEnd 
  term however
    doc 0
      freq 2
      pos 5384
      pos 16302
    doc 1
      freq 4
      pos 881
      pos 1954
      pos 2208
      pos 8800
    doc 2
      freq 7
      pos 632
      pos 950
      pos 1082
      pos 4083
      pos 4620
      pos 5935
      pos 5986
    doc 3
      freq 6
      pos 666
      pos 2762
      pos 2922
      pos 4254
      pos 5648
      pos 5825
    doc 4
      freq 1
      pos 1224
    doc 6
      freq 2
      pos 1286
      pos 2006
    doc 9
      freq 1
      pos 245
    doc 10
      freq 24
      pos 480
      pos 545
      pos 953
      pos 1491
      pos 1654
      pos 2789
      pos 3111
      pos 4341
      pos 5110
      pos 7583
      pos 7690
      pos 7869
      pos 8798
      pos 8890
      pos 9130
      pos 9276
      pos 9353
      pos 9446
      pos 9621
      pos 9875
      pos 10203
      pos 10253
      pos 10857
      pos 11056
    doc 11
      freq 2
      pos 1395
      pos 9378
    doc 12
      freq 19
      pos 961
      pos 1373
      pos 1920
      pos 2364
      pos 2430
      pos 3350
      pos 3724
      pos 4539
      pos 4940
      pos 5535
      pos 5592
      pos 6052
      pos 6478
      pos 6854
      pos 8445
      pos 8506
      pos 8671
      pos 8755
      pos 8805
    doc 13
      freq 10
      pos 949
      pos 1645
      pos 1726
      pos 1852
      pos 2039
      pos 2633
      pos 3739
      pos 3888
      pos 3932
      pos 4561
    doc 14
      freq 6
      pos 396
      pos 535
      pos 2070
      pos 2537
      pos 2727
      pos 2859
    doc 15
      freq 5
      pos 2621
      pos 2644
      pos 3037
      pos 3116
      pos 3270
    doc 17
      freq 1
      pos 363
    skipList 
      level 0
        skipDoc 10
        skipDocFP 1052508
        impacts 
          impact 
            freq 1
            norm 95
          impact 
            freq 2
            norm 101
          impact 
            freq 6
            norm 107
          impact 
            freq 7
            norm 108
          impact 
            freq 24
            norm 116
        impactsEnd 
  term hp11
    doc 1
      freq 1
      pos 9551
    doc 3
      freq 1
      pos 5916
  term hp6f3prft3capyfjvowgfog63pqfqrzscjbshw67
    doc 11
      freq 1
      pos 10390
  term hqbucljxf
    doc 10
      freq 1
      pos 6849
  term hr4ulglb71awcnc9ittmzxquiw7oi0fuemzjyekawgg6qu7ux5r
    doc 11
      freq 1
      pos 10156
  term hredfefwj7
    doc 10
      freq 1
      pos 12684
  term hsj50lawspuvycpm3p4daki1knuu41wgtceahacbxwqtzcun9ufe2abl
    doc 10
      freq 1
      pos 6257
  term hso0uyj7umxrkl
    doc 10
      freq 1
      pos 12573
  term htab
    doc 11
      freq 1
      pos 3954
  term htavaktjymjiqzbehy3yckmaupisqpvnzgjatl7gtu21mljew4iw0m2nu0iq
    doc 11
      freq 1
      pos 10187
  term html
    doc 12
      freq 1
      pos 7656
  term html.charters
    doc 0
      freq 1
      pos 1099
  term hto1crhirg4zde6zsq1wlkar21
    doc 11
      freq 1
      pos 10121
  term http
    doc 0
      freq 2
      pos 1097
      pos 17479
    doc 1
      freq 1
      pos 9860
    doc 2
      freq 10
      pos 2281
      pos 2296
      pos 2382
      pos 2443
      pos 2762
      pos 2785
      pos 2823
      pos 2890
      pos 3433
      pos 6657
    doc 3
      freq 1
      pos 6209
    doc 4
      freq 2
      pos 5062
      pos 6364
    doc 5
      freq 1
      pos 4694
    doc 6
      freq 1
      pos 3494
    doc 7
      freq 1
      pos 3199
    doc 8
      freq 1
      pos 2416
    doc 9
      freq 1
      pos 2061
    doc 10
      freq 13
      pos 5600
      pos 5610
      pos 10772
      pos 10804
      pos 11518
      pos 11621
      pos 11716
      pos 11817
      pos 11911
      pos 13269
      pos 13277
      pos 13427
      pos 13722
    doc 11
      freq 4
      pos 7644
      pos 10583
      pos 10611
      pos 10883
    doc 12
      freq 2
      pos 7649
      pos 9733
    doc 13
      freq 6
      pos 1700
      pos 1738
      pos 6797
      pos 6808
      pos 6900
      pos 7348
    doc 14
      freq 1
      pos 5814
    doc 15
      freq 1
      pos 4333
    doc 16
      freq 3
      pos 1661
      pos 2673
      pos 2944
    doc 17
      freq 1
      pos 2668
    doc 18
      freq 1
      pos 2456
    skipList 
      level 0
        skipDoc 7
        skipDocFP 1055491
        impacts 
          impact 
            freq 1
            norm 100
          impact 
            freq 10
            norm 108
        impactsEnd 
        skipDoc 15
        skipDocFP 1055962
        impacts 
          impact 
            freq 1
            norm 95
          impact 
            freq 6
            norm 109
          impact 
            freq 13
            norm 116
        impactsEnd 
  term https
    doc 2
      freq 1
      pos 2361
    doc 10
      freq 6
      pos 5602
      pos 5612
      pos 6587
      pos 6660
      pos 7303
      pos 7375
  term hub
    doc 2
      freq 3
      pos 255
      pos 3669
      pos 3928
  term hubmib
    doc 2
      freq 9
      pos 3743
      pos 3771
      pos 3779
      pos 3851
      pos 3881
      pos 3984
      pos 4017
      pos 4032
      pos 4055
  term huge
    doc 12
      freq 1
      pos 5735
    doc 13
      freq 1
      pos 4009
  term hughes
    doc 6
      freq 1
      pos 3135
  term huguenin
    doc 11
      freq 2
      pos 9451
      pos 9485
  term huitem
    doc 12
      freq 3
      pos 7262
      pos 7315
      pos 7608
  term human
    doc 1
      freq 2
      pos 6232
      pos 6269
    doc 10
      freq 1
      pos 760
    doc 11
      freq 2
      pos 1207
      pos 3935
    doc 13
      freq 2
      pos 887
      pos 1620
    doc 18
      freq 1
      pos 1892
  term humans
    doc 10
      freq 1
      pos 738
  term hundredths
    doc 0
      freq 2
      pos 6151
      pos 9340
  term hungry.example.net
    doc 11
      freq 1
      pos 4465
  term hurdles
    doc 6
      freq 1
      pos 2907
  term hurfgmn95ytgfx6rrhojepqowv4lyimvnvogs6dqrtkp3nngz5hipxyf
    doc 11
      freq 1
      pos 10195
  term huston
    doc 12
      freq 1
      pos 7714
  term hv0
    doc 11
      freq 1
      pos 10474
  term hvvaqhqpowmvaiqhi6g8mpolkteiypwcciqokgwbyeqxudbmxzs
    doc 11
      freq 1
      pos 10207
  term hxoy
    doc 11
      freq 1
      pos 10186
  term hypertext
    doc 13
      freq 1
      pos 6897
  term hyphen
    doc 14
      freq 2
      pos 2083
      pos 2283
  term hyphenated
    doc 11
      freq 1
      pos 7652
  term i.e
    doc 0
      freq 2
      pos 6687
      pos 14776
    doc 1
      freq 4
      pos 6639
      pos 8145
      pos 8327
      pos 8364
    doc 3
      freq 3
      pos 2687
      pos 2880
      pos 5321
    doc 4
      freq 1
      pos 4508
    doc 5
      freq 5
      pos 1276
      pos 1319
      pos 2502
      pos 2528
      pos 3038
    doc 6
      freq 1
      pos 1477
    doc 9
      freq 1
      pos 1303
    doc 10
      freq 4
      pos 1027
      pos 5187
      pos 8557
      pos 13038
    doc 12
      freq 3
      pos 4220
      pos 4634
      pos 5498
    doc 13
      freq 1
      pos 1606
    doc 14
      freq 3
      pos 516
      pos 2243
      pos 2367
    doc 16
      freq 1
      pos 891
    doc 17
      freq 2
      pos 125
      pos 1518
    skipList 
      level 0
        skipDoc 10
        skipDocFP 1058983
        impacts 
          impact 
            freq 1
            norm 95
          impact 
            freq 5
            norm 104
        impactsEnd 
  term i06
    doc 6
      freq 1
      pos 2930
  term i1
    doc 6
      freq 2
      pos 343
      pos 2869
  term i10
    doc 6
      freq 2
      pos 703
      pos 3008
  term i11
    doc 6
      freq 2
      pos 769
      pos 3043
  term i12
    doc 6
      freq 3
      pos 763
      pos 786
      pos 3062
  term i2
    doc 6
      freq 2
      pos 1688
      pos 2893
  term i3
    doc 6
      freq 2
      pos 431
      pos 2904
  term i4
    doc 6
      freq 2
      pos 449
      pos 2919
  term i5
    doc 6
      freq 2
      pos 344
      pos 2933
    doc 11
      freq 1
      pos 10375
  term i6
    doc 6
      freq 2
      pos 345
      pos 2951
  term i7
    doc 6
      freq 2
      pos 346
      pos 2966
  term i8
    doc 6
      freq 2
      pos 569
      pos 2986
  term i8k
    doc 11
      freq 1
      pos 10194
  term i9
    doc 6
      freq 2
      pos 2215
      pos 2994
  term ia5string
    doc 17
      freq 2
      pos 921
      pos 2351
  term iab
    doc 2
      freq 27
      pos 182
      pos 191
      pos 358
      pos 468
      pos 620
      pos 1070
      pos 1464
      pos 1839
      pos 2212
      pos 2234
      pos 2449
      pos 2693
      pos 2942
      pos 3198
      pos 3439
      pos 3482
      pos 3865
      pos 4249
      pos 4657
      pos 5018
      pos 5414
      pos 5819
      pos 6212
      pos 6326
      pos 6340
      pos 6389
      pos 6720
    doc 12
      freq 1
      pos 7515
  term iablink
    doc 2
      freq 2
      pos 1788
      pos 2337
  term iaids
    doc 15
      freq 1
      pos 2561
  term iana
    doc 0
      freq 3
      pos 162
      pos 15807
      pos 15818
    doc 1
      freq 14
      pos 363
      pos 2522
      pos 2531
      pos 3735
      pos 3746
      pos 5122
      pos 5125
      pos 6086
      pos 6095
      pos 7741
      pos 7755
      pos 7805
      pos 8953
      pos 8956
    doc 2
      freq 4
      pos 2196
      pos 3121
      pos 6190
      pos 6198
    doc 3
      freq 6
      pos 1841
      pos 1926
      pos 1988
      pos 2002
      pos 4336
      pos 4339
    doc 4
      freq 14
      pos 239
      pos 4742
      pos 4771
      pos 4804
      pos 4866
      pos 4868
      pos 4926
      pos 4954
      pos 5068
      pos 5092
      pos 5120
      pos 5310
      pos 5880
      pos 5915
    doc 5
      freq 7
      pos 328
      pos 3693
      pos 3699
      pos 3817
      pos 3919
      pos 4032
      pos 4151
    doc 7
      freq 5
      pos 141
      pos 1679
      pos 1682
      pos 1703
      pos 1719
    doc 8
      freq 31
      pos 20
      pos 96
      pos 117
      pos 187
      pos 199
      pos 203
      pos 222
      pos 335
      pos 337
      pos 474
      pos 484
      pos 523
      pos 570
      pos 799
      pos 811
      pos 853
      pos 901
      pos 1126
      pos 1140
      pos 1179
      pos 1226
      pos 1321
      pos 1360
      pos 1407
      pos 1440
      pos 1511
      pos 1549
      pos 1670
      pos 1735
      pos 1931
      pos 2154
    doc 10
      freq 5
      pos 306
      pos 11443
      pos 11461
      pos 11931
      pos 12011
    doc 11
      freq 1
      pos 7425
    doc 16
      freq 2
      pos 1639
      pos 1674
    doc 17
      freq 3
      pos 1943
      pos 1975
      pos 1986
    skipList 
      level 0
        skipDoc 8
        skipDocFP 1061556
        impacts 
          impact 
            freq 31
            norm 97
        impactsEnd 
  term iapp
    doc 2
      freq 2
      pos 6066
      pos 6109
  term ias
    doc 15
      freq 1
      pos 2601
  term iasa
    doc 0
      freq 1
      pos 17541
    doc 1
      freq 1
      pos 9922
    doc 2
      freq 1
      pos 6719
    doc 3
      freq 1
      pos 6271
    doc 4
      freq 1
      pos 6426
    doc 5
      freq 1
      pos 4756
    doc 6
      freq 1
      pos 3556
    doc 7
      freq 1
      pos 3261
    doc 8
      freq 1
      pos 2478
    doc 9
      freq 1
      pos 2123
    doc 10
      freq 1
      pos 13784
    doc 11
      freq 1
      pos 10945
    doc 12
      freq 1
      pos 9795
    doc 13
      freq 1
      pos 7410
    doc 14
      freq 1
      pos 5876
    doc 15
      freq 1
      pos 4395
    doc 16
      freq 1
      pos 3006
    doc 17
      freq 1
      pos 2730
    doc 18
      freq 1
      pos 2518
    skipList 
      level 0
        skipDoc 7
        skipDocFP 1063539
        impacts 
          impact 
            freq 1
            norm 100
        impactsEnd 
        skipDoc 15
        skipDocFP 1063844
        impacts 
          impact 
            freq 1
            norm 95
        impactsEnd 
  term ic127mqmx4ua5cscccaqqmknyl
    doc 11
      freq 1
      pos 9949
  term ichir
    doc 4
      freq 1
      pos 5491
  term icmp
    doc 4
      freq 74
      pos 143
      pos 156
      pos 231
      pos 235
      pos 294
      pos 424
      pos 473
      pos 575
      pos 744
      pos 1013
      pos 1370
      pos 1757
      pos 1811
      pos 1875
      pos 2054
      pos 2079
      pos 2316
      pos 2697
      pos 2720
      pos 2966
      pos 3203
      pos 3439
      pos 3629
      pos 3711
      pos 3801
      pos 4027
      pos 4029
      pos 4054
      pos 4077
      pos 4091
      pos 4097
      pos 4099
      pos 4131
      pos 4176
      pos 4179
      pos 4263
      pos 4286
      pos 4322
      pos 4345
      pos 4352
      pos 4388
      pos 4457
      pos 4501
      pos 4568
      pos 4591
      pos 4607
      pos 4618
      pos 4652
      pos 4690
      pos 4756
      pos 4793
      pos 4887
      pos 5032
      pos 5158
      pos 5403
      pos 5442
      pos 5457
      pos 5533
      pos 5598
      pos 5610
      pos 5638
      pos 5715
      pos 5722
      pos 5735
      pos 5741
      pos 5754
      pos 5818
      pos 5849
      pos 5864
      pos 5928
      pos 5970
      pos 6026
      pos 6037
      pos 6103
    doc 7
      freq 1
      pos 2001
  term icmpv6
    doc 4
      freq 112
      pos 32
      pos 115
      pos 120
      pos 142
      pos 155
      pos 182
      pos 208
      pos 246
      pos 311
      pos 334
      pos 367
      pos 383
      pos 423
      pos 472
      pos 476
      pos 499
      pos 501
      pos 534
      pos 550
      pos 579
      pos 675
      pos 683
      pos 743
      pos 758
      pos 760
      pos 799
      pos 802
      pos 828
      pos 989
      pos 1012
      pos 1042
      pos 1067
      pos 1180
      pos 1250
      pos 1272
      pos 1277
      pos 1316
      pos 1355
      pos 1369
      pos 1378
      pos 1418
      pos 1433
      pos 1481
      pos 1506
      pos 1538
      pos 1541
      pos 1559
      pos 1597
      pos 1632
      pos 1649
      pos 1655
      pos 1756
      pos 1834
      pos 1845
      pos 1868
      pos 2067
      pos 2078
      pos 2085
      pos 2141
      pos 2163
      pos 2265
      pos 2315
      pos 2719
      pos 2732
      pos 2807
      pos 2829
      pos 2924
      pos 2965
      pos 3052
      pos 3074
      pos 3145
      pos 3173
      pos 3202
      pos 3288
      pos 3310
      pos 3354
      pos 3372
      pos 3413
      pos 3438
      pos 3473
      pos 3519
      pos 3539
      pos 3597
      pos 3628
      pos 3666
      pos 3776
      pos 3800
      pos 3832
      pos 3946
      pos 3958
      pos 4090
      pos 4500
      pos 4748
      pos 4811
      pos 4860
      pos 4886
      pos 4934
      pos 4966
      pos 5065
      pos 5071
      pos 5102
      pos 5139
      pos 5157
      pos 5168
      pos 5237
      pos 5402
      pos 5532
      pos 5817
      pos 5907
      pos 5984
      pos 6036
      pos 6102
  term iczvxqwbtvr
    doc 10
      freq 1
      pos 12510
  term id
    doc 0
      freq 33
      pos 580
      pos 710
      pos 1439
      pos 1509
      pos 1524
      pos 1976
      pos 2395
      pos 4472
      pos 4536
      pos 4622
      pos 6231
      pos 6536
      pos 6570
      pos 6642
      pos 6678
      pos 6697
      pos 6730
      pos 7614
      pos 7636
      pos 8044
      pos 8066
      pos 9131
      pos 9160
      pos 11833
      pos 12425
      pos 12961
      pos 12969
      pos 12980
      pos 13096
      pos 13306
      pos 13356
      pos 13398
      pos 16296
    doc 1
      freq 60
      pos 269
      pos 1683
      pos 1698
      pos 2308
      pos 2495
      pos 2497
      pos 2586
      pos 2610
      pos 2616
      pos 2627
      pos 2651
      pos 2672
      pos 2704
      pos 2729
      pos 2736
      pos 2751
      pos 2887
      pos 2997
      pos 3008
      pos 3276
      pos 3591
      pos 3620
      pos 3844
      pos 4114
      pos 4122
      pos 4148
      pos 4171
      pos 4198
      pos 4214
      pos 4279
      pos 4299
      pos 4307
      pos 4518
      pos 5275
      pos 5286
      pos 5332
      pos 5397
      pos 5423
      pos 5438
      pos 5445
      pos 5456
      pos 5462
      pos 5514
      pos 5555
      pos 5735
      pos 6111
      pos 7100
      pos 7111
      pos 7117
      pos 7170
      pos 7231
      pos 7288
      pos 7297
      pos 7303
      pos 7342
      pos 7345
      pos 7361
      pos 7791
      pos 8754
      pos 8797
    doc 3
      freq 6
      pos 2016
      pos 2028
      pos 2061
      pos 2075
      pos 2084
      pos 2093
    doc 5
      freq 1
      pos 2688
    doc 8
      freq 2
      pos 1011
      pos 1055
    doc 10
      freq 19
      pos 638
      pos 754
      pos 4255
      pos 4971
      pos 6345
      pos 6630
      pos 7001
      pos 7147
      pos 7360
      pos 8043
      pos 8147
      pos 8152
      pos 8177
      pos 8228
      pos 8571
      pos 8578
      pos 8587
      pos 8619
      pos 8761
    doc 11
      freq 52
      pos 1473
      pos 1757
      pos 1981
      pos 2377
      pos 2572
      pos 2692
      pos 2772
      pos 2876
      pos 3380
      pos 3527
      pos 3630
      pos 3823
      pos 4017
      pos 4141
      pos 4288
      pos 4467
      pos 4680
      pos 4925
      pos 5049
      pos 5171
      pos 5329
      pos 5474
      pos 5635
      pos 5812
      pos 5952
      pos 6170
      pos 6360
      pos 6464
      pos 6625
      pos 6701
      pos 6780
      pos 6872
      pos 6979
      pos 7127
      pos 7175
      pos 7393
      pos 7524
      pos 7649
      pos 7750
      pos 7867
      pos 8054
      pos 8090
      pos 8145
      pos 8152
      pos 8337
      pos 8486
      pos 8615
      pos 8749
      pos 8839
      pos 8930
      pos 9085
      pos 9275
    doc 16
      freq 2
      pos 1976
      pos 2344
    doc 17
      freq 34
      pos 505
      pos 521
      pos 539
      pos 542
      pos 835
      pos 839
      pos 842
      pos 847
      pos 850
      pos 855
      pos 858
      pos 876
      pos 879
      pos 883
      pos 901
      pos 904
      pos 911
      pos 914
      pos 2185
      pos 2188
      pos 2225
      pos 2229
      pos 2231
      pos 2250
      pos 2262
      pos 2266
      pos 2269
      pos 2274
      pos 2277
      pos 2282
      pos 2286
      pos 2291
      pos 2341
      pos 2344
    skipList 
      level 0
        skipDoc 16
        skipDocFP 1067636
        impacts 
          impact 
            freq 2
            norm 97
          impact 
            freq 6
            norm 107
          impact 
            freq 60
            norm 113
        impactsEnd 
  term id3ngtocpxytmwf6jnjypdqioxvlodlmr
    doc 10
      freq 1
      pos 12475
  term id:y7vek9j9hyo.wl
    doc 12
      freq 1
      pos 7643
  term idea
    doc 12
      freq 1
      pos 4760
    doc 15
      freq 1
      pos 3152
  term ideally
    doc 10
      freq 1
      pos 1211
    doc 11
      freq 1
      pos 7194
  term ideas
    doc 13
      freq 1
      pos 6983
  term ident
    doc 10
      freq 8
      pos 4820
      pos 4823
      pos 4826
      pos 4831
      pos 4834
      pos 4837
      pos 4840
      pos 4846
  term identical
    doc 1
      freq 2
      pos 3926
      pos 3937
    doc 10
      freq 1
      pos 5986
  term identifiabl
    doc 12
      freq 1
      pos 1383
    doc 13
      freq 1
      pos 2335
  term identification
    doc 5
      freq 1
      pos 446
    doc 6
      freq 1
      pos 2465
    doc 7
      freq 4
      pos 776
      pos 1888
      pos 2166
      pos 2170
    doc 13
      freq 2
      pos 2350
      pos 6479
  term identified
    doc 1
      freq 7
      pos 2938
      pos 2943
      pos 3392
      pos 3409
      pos 4441
      pos 4673
      pos 8789
    doc 4
      freq 7
      pos 553
      pos 698
      pos 1410
      pos 2748
      pos 2994
      pos 3230
      pos 3533
    doc 6
      freq 2
      pos 2578
      pos 2771
    doc 10
      freq 2
      pos 3523
      pos 8792
    doc 11
      freq 1
      pos 2649
    doc 12
      freq 1
      pos 6549
    doc 13
      freq 2
      pos 5512
      pos 6290
    doc 15
      freq 2
      pos 132
      pos 2620
    doc 17
      freq 8
      pos 503
      pos 528
      pos 865
      pos 890
      pos 1950
      pos 2172
      pos 2212
      pos 2237
    skipList 
      level 0
        skipDoc 15
        skipDocFP 1072252
        impacts 
          impact 
            freq 2
            norm 101
          impact 
            freq 7
            norm 108
        impactsEnd 
  term identifier
    doc 0
      freq 23
      pos 1258
      pos 1263
      pos 1268
      pos 1272
      pos 1279
      pos 1293
      pos 1303
      pos 1318
      pos 1327
      pos 1339
      pos 1350
      pos 1367
      pos 1383
      pos 1392
      pos 2279
      pos 6514
      pos 10083
      pos 12294
      pos 12346
      pos 14374
      pos 14379
      pos 15821
      pos 15831
    doc 1
      freq 14
      pos 1661
      pos 2410
      pos 3109
      pos 3165
      pos 3176
      pos 3250
      pos 3257
      pos 3263
      pos 3268
      pos 3280
      pos 3488
      pos 3493
      pos 3498
      pos 4210
    doc 3
      freq 2
      pos 1724
      pos 1749
    doc 4
      freq 6
      pos 3585
      pos 3603
      pos 3605
      pos 3756
      pos 3782
      pos 3784
    doc 5
      freq 4
      pos 1209
      pos 1334
      pos 1907
      pos 1928
    doc 8
      freq 10
      pos 73
      pos 144
      pos 150
      pos 1138
      pos 1150
      pos 1293
      pos 1314
      pos 1318
      pos 1331
      pos 1488
    doc 10
      freq 4
      pos 827
      pos 8650
      pos 9800
      pos 9998
    doc 11
      freq 5
      pos 393
      pos 7021
      pos 7045
      pos 7096
      pos 9685
    doc 12
      freq 2
      pos 1343
      pos 5887
    doc 15
      freq 2
      pos 2555
      pos 3157
    doc 17
      freq 16
      pos 525
      pos 807
      pos 838
      pos 846
      pos 854
      pos 862
      pos 887
      pos 910
      pos 949
      pos 1954
      pos 2265
      pos 2273
      pos 2281
      pos 2290
      pos 2328
      pos 2340
    skipList 
      level 0
        skipDoc 11
        skipDocFP 1073182
        impacts 
          impact 
            freq 10
            norm 97
          impact 
            freq 14
            norm 113
          impact 
            freq 23
            norm 120
        impactsEnd 
  term identifiers
    doc 0
      freq 3
      pos 3629
      pos 4145
      pos 10986
    doc 1
      freq 3
      pos 263
      pos 2953
      pos 3063
    doc 2
      freq 1
      pos 1887
    doc 7
      freq 2
      pos 836
      pos 2246
    doc 8
      freq 4
      pos 139
      pos 1134
      pos 1684
      pos 1717
    doc 10
      freq 3
      pos 9811
      pos 11163
      pos 13349
    doc 11
      freq 1
      pos 7031
    doc 12
      freq 1
      pos 5749
    doc 15
      freq 2
      pos 2560
      pos 3987
    doc 17
      freq 2
      pos 581
      pos 706
    skipList 
      level 0
        skipDoc 12
        skipDocFP 1075061
        impacts 
          impact 
            freq 4
            norm 97
        impactsEnd 
  term identifies
    doc 0
      freq 4
      pos 1889
      pos 1927
      pos 9698
      pos 12374
    doc 1
      freq 3
      pos 2743
      pos 3887
      pos 4481
    doc 4
      freq 2
      pos 3332
      pos 3457
    doc 5
      freq 4
      pos 1624
      pos 2654
      pos 2663
      pos 3730
    doc 15
      freq 1
      pos 180
    doc 17
      freq 1
      pos 1118
  term identify
    doc 0
      freq 11
      pos 5526
      pos 13104
      pos 13124
      pos 13226
      pos 13318
      pos 13443
      pos 13529
      pos 13633
      pos 13723
      pos 16178
      pos 17398
    doc 1
      freq 8
      pos 513
      pos 767
      pos 1930
      pos 2128
      pos 3097
      pos 3122
      pos 3239
      pos 9779
    doc 2
      freq 1
      pos 6576
    doc 3
      freq 1
      pos 6128
    doc 4
      freq 4
      pos 574
      pos 1046
      pos 1792
      pos 6283
    doc 5
      freq 1
      pos 4613
    doc 6
      freq 2
      pos 960
      pos 3413
    doc 7
      freq 3
      pos 95
      pos 336
      pos 3118
    doc 8
      freq 2
      pos 357
      pos 2335
    doc 9
      freq 1
      pos 1980
    doc 10
      freq 3
      pos 3595
      pos 10348
      pos 13641
    doc 11
      freq 1
      pos 10802
    doc 12
      freq 1
      pos 9652
    doc 13
      freq 1
      pos 7267
    doc 14
      freq 1
      pos 5733
    doc 15
      freq 4
      pos 2163
      pos 2574
      pos 2609
      pos 4252
    doc 16
      freq 1
      pos 2863
    doc 17
      freq 3
      pos 584
      pos 1133
      pos 2587
    doc 18
      freq 1
      pos 2375
    skipList 
      level 0
        skipDoc 7
        skipDocFP 1076190
        impacts 
          impact 
            freq 3
            norm 100
          impact 
            freq 4
            norm 108
          impact 
            freq 8
            norm 113
          impact 
            freq 11
            norm 120
        impactsEnd 
        skipDoc 15
        skipDocFP 1076843
        impacts 
          impact 
            freq 1
            norm 95
          impact 
            freq 2
            norm 97
          impact 
            freq 4
            norm 104
        impactsEnd 
  term identifying
    doc 0
      freq 1
      pos 8937
    doc 1
      freq 4
      pos 1405
      pos 2152
      pos 3311
      pos 4519
    doc 7
      freq 1
      pos 30
    doc 10
      freq 1
      pos 128
  term identities
    doc 10
      freq 5
      pos 1621
      pos 2904
      pos 4627
      pos 7414
      pos 7754
    doc 15
      freq 1
      pos 3148
  term identity
    doc 0
      freq 2
      pos 1021
      pos 1071
    doc 1
      freq 1
      pos 2961
    doc 2
      freq 1
      pos 2310
    doc 10
      freq 284
      pos 22
      pos 107
      pos 143
      pos 152
      pos 154
      pos 175
      pos 201
      pos 235
      pos 244
      pos 256
      pos 282
      pos 317
      pos 325
      pos 340
      pos 346
      pos 351
      pos 399
      pos 414
      pos 426
      pos 470
      pos 662
      pos 780
      pos 790
      pos 866
      pos 935
      pos 946
      pos 963
      pos 1021
      pos 1066
      pos 1253
      pos 1465
      pos 1485
      pos 1545
      pos 1568
      pos 1582
      pos 1616
      pos 1704
      pos 1826
      pos 1871
      pos 1950
      pos 1983
      pos 2004
      pos 2033
      pos 2091
      pos 2333
      pos 2347
      pos 2374
      pos 2378
      pos 2398
      pos 2437
      pos 2459
      pos 2475
      pos 2492
      pos 2506
      pos 2517
      pos 2540
      pos 2544
      pos 2653
      pos 2881
      pos 2909
      pos 2972
      pos 3242
      pos 3306
      pos 3311
      pos 3321
      pos 3336
      pos 3340
      pos 3376
      pos 3389
      pos 3481
      pos 3614
      pos 3646
      pos 3682
      pos 3729
      pos 3745
      pos 3758
      pos 3771
      pos 3788
      pos 3816
      pos 3826
      pos 3857
      pos 3891
      pos 3902
      pos 3994
      pos 4025
      pos 4049
      pos 4059
      pos 4187
      pos 4200
      pos 4238
      pos 4269
      pos 4307
      pos 4434
      pos 4528
      pos 4598
      pos 4602
      pos 4640
      pos 4667
      pos 4690
      pos 4703
      pos 4734
      pos 4754
      pos 4756
      pos 4772
      pos 4774
      pos 4803
      pos 4804
      pos 4807
      pos 4810
      pos 4815
      pos 4817
      pos 4853
      pos 4878
      pos 4931
      pos 4942
      pos 5155
      pos 5402
      pos 5436
      pos 5445
      pos 5498
      pos 5551
      pos 5571
      pos 5606
      pos 5659
      pos 5689
      pos 5725
      pos 5741
      pos 5754
      pos 5767
      pos 5793
      pos 5823
      pos 5907
      pos 5929
      pos 5931
      pos 5954
      pos 5988
      pos 5996
      pos 6033
      pos 6057
      pos 6182
      pos 6275
      pos 6446
      pos 6450
      pos 6461
      pos 6528
      pos 6573
      pos 6651
      pos 6658
      pos 6732
      pos 6765
      pos 6783
      pos 6786
      pos 6807
      pos 6969
      pos 7050
      pos 7056
      pos 7086
      pos 7211
      pos 7273
      pos 7291
      pos 7365
      pos 7373
      pos 7391
      pos 7429
      pos 7524
      pos 7528
      pos 7603
      pos 7683
      pos 7770
      pos 7851
      pos 7948
      pos 8011
      pos 8035
      pos 8054
      pos 8065
      pos 8072
      pos 8101
      pos 8105
      pos 8126
      pos 8161
      pos 8170
      pos 8269
      pos 8352
      pos 8373
      pos 8390
      pos 8406
      pos 8421
      pos 8469
      pos 8539
      pos 8600
      pos 8623
      pos 8690
      pos 8717
      pos 8739
      pos 8746
      pos 8989
      pos 9050
      pos 9106
      pos 9252
      pos 9254
      pos 9321
      pos 9398
      pos 9412
      pos 9479
      pos 9560
      pos 9586
      pos 9724
      pos 9887
      pos 9889
      pos 9944
      pos 10000
      pos 10215
      pos 10321
      pos 10334
      pos 10376
      pos 10410
      pos 10748
      pos 10790
      pos 10794
      pos 10812
      pos 10824
      pos 11017
      pos 11035
      pos 11084
      pos 11127
      pos 11132
      pos 11168
      pos 11170
      pos 11207
      pos 11222
      pos 11230
      pos 11250
      pos 11262
      pos 11327
      pos 11376
      pos 11402
      pos 11437
      pos 11475
      pos 11489
      pos 11491
      pos 11525
      pos 11531
      pos 11545
      pos 11551
      pos 11582
      pos 11597
      pos 11634
      pos 11639
      pos 11662
      pos 11729
      pos 11767
      pos 11840
      pos 11846
      pos 11875
      pos 11924
      pos 11927
      pos 11938
      pos 11969
      pos 11993
      pos 12005
      pos 12018
      pos 12052
      pos 12097
      pos 12282
      pos 12288
      pos 12290
      pos 12388
      pos 12535
      pos 12699
      pos 12834
      pos 12879
      pos 12899
      pos 12930
      pos 12951
      pos 12968
      pos 12987
      pos 13025
      pos 13058
      pos 13065
      pos 13084
      pos 13176
      pos 13304
      pos 13334
      pos 13463
    doc 11
      freq 1
      pos 3799
    doc 15
      freq 1
      pos 2558
    doc 17
      freq 1
      pos 186
  term idfieldlengthmismatches
    doc 0
      freq 3
      pos 7647
      pos 8080
      pos 8122
  term idh
    doc 11
      freq 1
      pos 9937
  term idi
    doc 0
      freq 1
      pos 10329
  term idle
    doc 13
      freq 1
      pos 4113
  term idn
    doc 10
      freq 1
      pos 12798
  term idp
    doc 7
      freq 2
      pos 1091
      pos 2684
  term idrp
    doc 0
      freq 1
      pos 10853
  term ids
    doc 0
      freq 2
      pos 1555
      pos 4442
    doc 5
      freq 2
      pos 2695
      pos 2702
    doc 10
      freq 2
      pos 8532
      pos 8546
  term idsel
    doc 2
      freq 2
      pos 1786
      pos 2300
  term iec
    doc 0
      freq 1
      pos 16914
    doc 2
      freq 2
      pos 2523
      pos 2579
    doc 3
      freq 1
      pos 4405
    doc 6
      freq 1
      pos 2988
    doc 17
      freq 3
      pos 494
      pos 2008
      pos 2096
  term ieee
    doc 2
      freq 273
      pos 18
      pos 63
      pos 125
      pos 197
      pos 211
      pos 235
      pos 279
      pos 323
      pos 344
      pos 370
      pos 427
      pos 438
      pos 445
      pos 450
      pos 478
      pos 486
      pos 548
      pos 558
      pos 613
      pos 626
      pos 660
      pos 671
      pos 685
      pos 690
      pos 696
      pos 715
      pos 727
      pos 732
      pos 747
      pos 753
      pos 760
      pos 776
      pos 791
      pos 823
      pos 841
      pos 843
      pos 856
      pos 861
      pos 904
      pos 952
      pos 985
      pos 1002
      pos 1016
      pos 1035
      pos 1066
      pos 1076
      pos 1091
      pos 1102
      pos 1160
      pos 1191
      pos 1226
      pos 1241
      pos 1263
      pos 1290
      pos 1295
      pos 1307
      pos 1326
      pos 1338
      pos 1352
      pos 1363
      pos 1371
      pos 1375
      pos 1378
      pos 1381
      pos 1407
      pos 1436
      pos 1453
      pos 1458
      pos 1461
      pos 1470
      pos 1479
      pos 1551
      pos 1612
      pos 1621
      pos 1627
      pos 1640
      pos 1713
      pos 1730
      pos 1760
      pos 1781
      pos 1791
      pos 1810
      pos 1820
      pos 1845
      pos 1909
      pos 1917
      pos 1944
      pos 1984
      pos 2003
      pos 2024
      pos 2059
      pos 2092
      pos 2112
      pos 2187
      pos 2218
      pos 2288
      pos 2292
      pos 2350
      pos 2352
      pos 2367
      pos 2387
      pos 2390
      pos 2398
      pos 2419
      pos 2422
      pos 2428
      pos 2430
      pos 2455
      pos 2461
      pos 2471
      pos 2479
      pos 2481
      pos 2494
      pos 2499
      pos 2502
      pos 2515
      pos 2520
      pos 2550
      pos 2555
      pos 2557
      pos 2576
      pos 2616
      pos 2621
      pos 2651
      pos 2655
      pos 2657
      pos 2689
      pos 2699
      pos 2705
      pos 2707
      pos 2744
      pos 2748
      pos 2754
      pos 2771
      pos 2777
      pos 2838
      pos 2858
      pos 2876
      pos 2932
      pos 2948
      pos 3170
      pos 3204
      pos 3235
      pos 3412
      pos 3418
      pos 3423
      pos 3445
      pos 3488
      pos 3511
      pos 3525
      pos 3530
      pos 3532
      pos 3624
      pos 3646
      pos 3676
      pos 3707
      pos 3710
      pos 3728
      pos 3752
      pos 3785
      pos 3808
      pos 3834
      pos 3859
      pos 3871
      pos 3884
      pos 3912
      pos 4012
      pos 4027
      pos 4064
      pos 4089
      pos 4116
      pos 4140
      pos 4255
      pos 4334
      pos 4357
      pos 4375
      pos 4378
      pos 4431
      pos 4434
      pos 4470
      pos 4473
      pos 4493
      pos 4506
      pos 4535
      pos 4563
      pos 4582
      pos 4585
      pos 4617
      pos 4622
      pos 4663
      pos 4775
      pos 4842
      pos 4854
      pos 4891
      pos 4906
      pos 4924
      pos 4927
      pos 4930
      pos 4935
      pos 4938
      pos 4955
      pos 4983
      pos 4987
      pos 4989
      pos 4992
      pos 5001
      pos 5014
      pos 5024
      pos 5034
      pos 5081
      pos 5096
      pos 5107
      pos 5114
      pos 5130
      pos 5202
      pos 5249
      pos 5280
      pos 5282
      pos 5302
      pos 5317
      pos 5328
      pos 5352
      pos 5357
      pos 5382
      pos 5392
      pos 5406
      pos 5420
      pos 5429
      pos 5433
      pos 5446
      pos 5454
      pos 5535
      pos 5543
      pos 5598
      pos 5622
      pos 5630
      pos 5632
      pos 5641
      pos 5644
      pos 5647
      pos 5652
      pos 5658
      pos 5661
      pos 5667
      pos 5689
      pos 5695
      pos 5699
      pos 5707
      pos 5724
      pos 5732
      pos 5748
      pos 5757
      pos 5809
      pos 5816
      pos 5825
      pos 5856
      pos 5889
      pos 5960
      pos 6015
      pos 6026
      pos 6039
      pos 6041
      pos 6132
      pos 6218
      pos 6230
      pos 6251
      pos 6258
      pos 6283
      pos 6289
      pos 6298
      pos 6319
      pos 6332
      pos 6395
    doc 3
      freq 11
      pos 248
      pos 299
      pos 2924
      pos 3142
      pos 3178
      pos 4410
      pos 4448
      pos 4452
      pos 4467
      pos 5278
      pos 5777
    doc 7
      freq 2
      pos 1069
      pos 2643
  term ieee802
    doc 2
      freq 2
      pos 2763
      pos 2786
  term ieee802.11
    doc 2
      freq 1
      pos 2365
  term ieee802.3
    doc 3
      freq 1
      pos 4402
  term iesg
    doc 2
      freq 10
      pos 353
      pos 426
      pos 470
      pos 591
      pos 1939
      pos 2363
      pos 2384
      pos 2445
      pos 5493
      pos 5756
    doc 4
      freq 2
      pos 4842
      pos 5021
    doc 6
      freq 1
      pos 61
    doc 7
      freq 4
      pos 403
      pos 442
      pos 1548
      pos 1574
    doc 12
      freq 1
      pos 6831
    doc 16
      freq 1
      pos 1651
  term ietf
    doc 0
      freq 9
      pos 1080
      pos 1163
      pos 17335
      pos 17429
      pos 17473
      pos 17483
      pos 17521
      pos 17523
      pos 17537
    doc 1
      freq 8
      pos 9168
      pos 9716
      pos 9810
      pos 9854
      pos 9864
      pos 9902
      pos 9904
      pos 9918
    doc 2
      freq 128
      pos 20
      pos 66
      pos 199
      pos 215
      pos 321
      pos 342
      pos 399
      pos 418
      pos 458
      pos 491
      pos 499
      pos 515
      pos 518
      pos 552
      pos 562
      pos 566
      pos 609
      pos 628
      pos 651
      pos 658
      pos 695
      pos 774
      pos 782
      pos 819
      pos 832
      pos 850
      pos 884
      pos 890
      pos 919
      pos 928
      pos 938
      pos 962
      pos 990
      pos 998
      pos 1031
      pos 1064
      pos 1078
      pos 1087
      pos 1099
      pos 1158
      pos 1194
      pos 1214
      pos 1255
      pos 1282
      pos 1305
      pos 1418
      pos 1472
      pos 1493
      pos 1542
      pos 1670
      pos 1704
      pos 1733
      pos 1756
      pos 1790
      pos 1800
      pos 1802
      pos 1847
      pos 1929
      pos 2029
      pos 2045
      pos 2095
      pos 2184
      pos 2220
      pos 2239
      pos 2265
      pos 2371
      pos 2457
      pos 2701
      pos 2820
      pos 2834
      pos 2950
      pos 3206
      pos 3447
      pos 3490
      pos 3509
      pos 3742
      pos 3770
      pos 3850
      pos 3873
      pos 3880
      pos 4016
      pos 4031
      pos 4039
      pos 4054
      pos 4099
      pos 4257
      pos 4301
      pos 4314
      pos 4330
      pos 4361
      pos 4404
      pos 4499
      pos 4665
      pos 4740
      pos 4864
      pos 4871
      pos 4910
      pos 4972
      pos 5026
      pos 5161
      pos 5189
      pos 5333
      pos 5344
      pos 5374
      pos 5399
      pos 5422
      pos 5522
      pos 5529
      pos 5625
      pos 5780
      pos 5827
      pos 5859
      pos 6019
      pos 6029
      pos 6183
      pos 6207
      pos 6220
      pos 6233
      pos 6246
      pos 6334
      pos 6397
      pos 6513
      pos 6607
      pos 6651
      pos 6661
      pos 6699
      pos 6701
      pos 6715
    doc 3
      freq 7
      pos 6065
      pos 6159
      pos 6203
      pos 6213
      pos 6251
      pos 6253
      pos 6267
    doc 4
      freq 15
      pos 4815
      pos 4835
      pos 4846
      pos 4941
      pos 4973
      pos 4982
      pos 5001
      pos 5290
      pos 6220
      pos 6314
      pos 6358
      pos 6368
      pos 6406
      pos 6408
      pos 6422
    doc 5
      freq 7
      pos 4550
      pos 4644
      pos 4688
      pos 4698
      pos 4736
      pos 4738
      pos 4752
    doc 6
      freq 11
      pos 77
      pos 103
      pos 111
      pos 125
      pos 3350
      pos 3444
      pos 3488
      pos 3498
      pos 3536
      pos 3538
      pos 3552
    doc 7
      freq 14
      pos 217
      pos 401
      pos 445
      pos 532
      pos 613
      pos 1330
      pos 1571
      pos 3055
      pos 3149
      pos 3193
      pos 3203
      pos 3241
      pos 3243
      pos 3257
    doc 8
      freq 15
      pos 212
      pos 240
      pos 288
      pos 546
      pos 876
      pos 1202
      pos 1383
      pos 1749
      pos 2272
      pos 2366
      pos 2410
      pos 2420
      pos 2458
      pos 2460
      pos 2474
    doc 9
      freq 7
      pos 1917
      pos 2011
      pos 2055
      pos 2065
      pos 2103
      pos 2105
      pos 2119
    doc 10
      freq 7
      pos 13578
      pos 13672
      pos 13716
      pos 13726
      pos 13764
      pos 13766
      pos 13780
    doc 11
      freq 7
      pos 10739
      pos 10833
      pos 10877
      pos 10887
      pos 10925
      pos 10927
      pos 10941
    doc 12
      freq 8
      pos 4007
      pos 9589
      pos 9683
      pos 9727
      pos 9737
      pos 9775
      pos 9777
      pos 9791
    doc 13
      freq 8
      pos 377
      pos 7204
      pos 7298
      pos 7342
      pos 7352
      pos 7390
      pos 7392
      pos 7406
    doc 14
      freq 7
      pos 5670
      pos 5764
      pos 5808
      pos 5818
      pos 5856
      pos 5858
      pos 5872
    doc 15
      freq 9
      pos 1773
      pos 3777
      pos 4189
      pos 4283
      pos 4327
      pos 4337
      pos 4375
      pos 4377
      pos 4391
    doc 16
      freq 7
      pos 2800
      pos 2894
      pos 2938
      pos 2948
      pos 2986
      pos 2988
      pos 3002
    doc 17
      freq 7
      pos 2524
      pos 2618
      pos 2662
      pos 2672
      pos 2710
      pos 2712
      pos 2726
    doc 18
      freq 7
      pos 2312
      pos 2406
      pos 2450
      pos 2460
      pos 2498
      pos 2500
      pos 2514
    skipList 
      level 0
        skipDoc 7
        skipDocFP 1088800
        impacts 
          impact 
            freq 14
            norm 100
          impact 
            freq 128
            norm 108
        impactsEnd 
        skipDoc 15
        skipDocFP 1091935
        impacts 
          impact 
            freq 7
            norm 95
          impact 
            freq 15
            norm 97
        impactsEnd 
  term ietf's
    doc 2
      freq 1
      pos 3545
  term ietf.org
    doc 0
      freq 2
      pos 1104
      pos 17525
    doc 1
      freq 1
      pos 9906
    doc 2
      freq 3
      pos 593
      pos 619
      pos 6703
    doc 3
      freq 1
      pos 6255
    doc 4
      freq 1
      pos 6410
    doc 5
      freq 1
      pos 4740
    doc 6
      freq 1
      pos 3540
    doc 7
      freq 1
      pos 3245
    doc 8
      freq 1
      pos 2462
    doc 9
      freq 1
      pos 2107
    doc 10
      freq 1
      pos 13768
    doc 11
      freq 1
      pos 10929
    doc 12
      freq 1
      pos 9779
    doc 13
      freq 1
      pos 7394
    doc 14
      freq 1
      pos 5860
    doc 15
      freq 1
      pos 4379
    doc 16
      freq 1
      pos 2990
    doc 17
      freq 1
      pos 2714
    doc 18
      freq 1
      pos 2502
    skipList 
      level 0
        skipDoc 7
        skipDocFP 1094034
        impacts 
          impact 
            freq 1
            norm 100
          impact 
            freq 3
            norm 108
        impactsEnd 
        skipDoc 15
        skipDocFP 1094382
        impacts 
          impact 
            freq 1
            norm 95
        impactsEnd 
  term iewnmh2nacckk83lp
    doc 10
      freq 1
      pos 6211
  term if
    doc 0
      freq 61
      pos 406
      pos 1058
      pos 2126
      pos 2259
      pos 2779
      pos 2904
      pos 2984
      pos 3001
      pos 3258
      pos 3562
      pos 3620
      pos 3824
      pos 3855
      pos 3995
      pos 4031
      pos 4136
      pos 4324
      pos 4355
      pos 4604
      pos 4629
      pos 4939
      pos 4988
      pos 5049
      pos 5093
      pos 5102
      pos 5111
      pos 5126
      pos 5265
      pos 5310
      pos 5325
      pos 5340
      pos 5798
      pos 5867
      pos 5920
      pos 6061
      pos 6165
      pos 6240
      pos 6575
      pos 6743
      pos 7125
      pos 8236
      pos 9356
      pos 10669
      pos 10977
      pos 11188
      pos 11219
      pos 12554
      pos 12689
      pos 12704
      pos 13310
      pos 13376
      pos 13388
      pos 14143
      pos 14150
      pos 14300
      pos 14335
      pos 16351
      pos 16575
      pos 16709
      pos 16758
      pos 17284
    doc 1
      freq 66
      pos 882
      pos 1381
      pos 1504
      pos 1556
      pos 1608
      pos 1635
      pos 1722
      pos 2596
      pos 2881
      pos 2904
      pos 2917
      pos 3375
      pos 3500
      pos 3532
      pos 3782
      pos 3830
      pos 3927
      pos 4524
      pos 4644
      pos 4696
      pos 4724
      pos 4891
      pos 4917
      pos 4966
      pos 4991
      pos 5484
      pos 5496
      pos 5528
      pos 5754
      pos 5771
      pos 5791
      pos 5817
      pos 5871
      pos 5920
      pos 6194
      pos 6382
      pos 6453
      pos 6482
      pos 6497
      pos 6528
      pos 6552
      pos 6592
      pos 6628
      pos 6645
      pos 6659
      pos 6721
      pos 6733
      pos 6745
      pos 6817
      pos 6824
      pos 6956
      pos 6996
      pos 7014
      pos 7040
      pos 7139
      pos 7152
      pos 7204
      pos 7482
      pos 7501
      pos 8175
      pos 8541
      pos 8561
      pos 8594
      pos 9458
      pos 9468
      pos 9665
    doc 2
      freq 4
      pos 594
      pos 1126
      pos 3840
      pos 6462
    doc 3
      freq 29
      pos 1197
      pos 1721
      pos 1741
      pos 1786
      pos 1864
      pos 2049
      pos 2076
      pos 2142
      pos 2161
      pos 2291
      pos 2482
      pos 2500
      pos 2537
      pos 2559
      pos 2867
      pos 2979
      pos 3002
      pos 3093
      pos 3318
      pos 3383
      pos 3511
      pos 3546
      pos 3895
      pos 4255
      pos 4261
      pos 5231
      pos 5283
      pos 5369
      pos 6014
    doc 4
      freq 28
      pos 896
      pos 930
      pos 1087
      pos 1108
      pos 1137
      pos 1233
      pos 1376
      pos 1416
      pos 2271
      pos 2279
      pos 2339
      pos 2361
      pos 2442
      pos 2585
      pos 2597
      pos 2630
      pos 2659
      pos 2742
      pos 2988
      pos 3114
      pos 3127
      pos 3224
      pos 3356
      pos 3376
      pos 3527
      pos 4553
      pos 5667
      pos 6169
    doc 5
      freq 7
      pos 1295
      pos 2058
      pos 2487
      pos 3081
      pos 3441
      pos 3572
      pos 4499
    doc 6
      freq 8
      pos 1264
      pos 1874
      pos 1936
      pos 1981
      pos 2117
      pos 2241
      pos 2354
      pos 3299
    doc 7
      freq 1
      pos 3004
    doc 8
      freq 1
      pos 2221
    doc 9
      freq 8
      pos 842
      pos 974
      pos 1313
      pos 1322
      pos 1357
      pos 1445
      pos 1545
      pos 1866
    doc 10
      freq 42
      pos 1073
      pos 1138
      pos 1644
      pos 2014
      pos 2253
      pos 2285
      pos 2376
      pos 2435
      pos 2466
      pos 2572
      pos 2629
      pos 2669
      pos 2956
      pos 3078
      pos 3186
      pos 3586
      pos 3623
      pos 3714
      pos 3753
      pos 3855
      pos 4043
      pos 4118
      pos 4165
      pos 4216
      pos 4513
      pos 4571
      pos 4719
      pos 5173
      pos 5262
      pos 6716
      pos 7088
      pos 7650
      pos 8598
      pos 8621
      pos 9115
      pos 9762
      pos 9825
      pos 10049
      pos 10795
      pos 12402
      pos 12409
      pos 13527
    doc 11
      freq 33
      pos 709
      pos 1296
      pos 1366
      pos 1851
      pos 3291
      pos 3597
      pos 3735
      pos 4105
      pos 4388
      pos 4434
      pos 4562
      pos 4613
      pos 4808
      pos 4826
      pos 4831
      pos 4845
      pos 5292
      pos 5596
      pos 5762
      pos 5890
      pos 6098
      pos 6550
      pos 6570
      pos 7450
      pos 7480
      pos 7933
      pos 7971
      pos 8292
      pos 8418
      pos 8589
      pos 9807
      pos 9814
      pos 10688
    doc 12
      freq 48
      pos 482
      pos 1420
      pos 1788
      pos 2400
      pos 2578
      pos 2610
      pos 2691
      pos 3189
      pos 3431
      pos 3535
      pos 3739
      pos 4449
      pos 4640
      pos 4801
      pos 4823
      pos 4880
      pos 5136
      pos 5379
      pos 5475
      pos 5523
      pos 5998
      pos 6028
      pos 6090
      pos 6117
      pos 6426
      pos 8007
      pos 8203
      pos 8214
      pos 8217
      pos 8256
      pos 8308
      pos 8487
      pos 8567
      pos 8604
      pos 8649
      pos 8693
      pos 8736
      pos 8748
      pos 8817
      pos 8878
      pos 8897
      pos 8924
      pos 8949
      pos 9116
      pos 9141
      pos 9258
      pos 9268
      pos 9538
    doc 13
      freq 5
      pos 2476
      pos 2606
      pos 2655
      pos 2716
      pos 7153
    doc 14
      freq 23
      pos 697
      pos 744
      pos 775
      pos 912
      pos 949
      pos 1047
      pos 1090
      pos 1391
      pos 1435
      pos 1465
      pos 1480
      pos 1568
      pos 1611
      pos 1699
      pos 1728
      pos 1799
      pos 1924
      pos 1966
      pos 1988
      pos 2071
      pos 2268
      pos 2314
      pos 5619
    doc 15
      freq 20
      pos 680
      pos 778
      pos 807
      pos 958
      pos 979
      pos 1071
      pos 1265
      pos 1323
      pos 1439
      pos 1707
      pos 1941
      pos 1981
      pos 2237
      pos 2316
      pos 2440
      pos 2729
      pos 2753
      pos 2842
      pos 2929
      pos 4138
    doc 16
      freq 13
      pos 687
      pos 715
      pos 742
      pos 758
      pos 781
      pos 1182
      pos 1221
      pos 1256
      pos 1329
      pos 1346
      pos 1359
      pos 1398
      pos 2749
    doc 17
      freq 12
      pos 634
      pos 656
      pos 701
      pos 718
      pos 1112
      pos 1216
      pos 1230
      pos 1441
      pos 1622
      pos 1690
      pos 1931
      pos 2473
    doc 18
      freq 6
      pos 1055
      pos 1095
      pos 1329
      pos 1618
      pos 1713
      pos 2261
    skipList 
      level 0
        skipDoc 7
        skipDocFP 1095249
        impacts 
          impact 
            freq 1
            norm 100
          impact 
            freq 8
            norm 101
          impact 
            freq 29
            norm 107
          impact 
            freq 66
            norm 113
        impactsEnd 
        skipDoc 15
        skipDocFP 1098511
        impacts 
          impact 
            freq 8
            norm 95
          impact 
            freq 20
            norm 104
          impact 
            freq 23
            norm 107
          impact 
            freq 48
            norm 113
        impactsEnd 
  term ifindex
    doc 0
      freq 2
      pos 1568
      pos 5603
  term ifsrdiopoqzyoy2wrvghuhcsmbhwusfxi6p6q5toqxhmmz6ueo3svjssh49thygn
    doc 10
      freq 2
      pos 6560
      pos 6653
  term ifsvhf83avtv
    doc 11
      freq 1
      pos 10099
  term ift.client.example.com
    doc 11
      freq 1
      pos 9277
  term ift.client.example.net
    doc 11
      freq 1
      pos 9257
  term iftgw.example.com
    doc 11
      freq 1
      pos 9253
  term ignjatic
    doc 5
      freq 1
      pos 4378
  term ignor
    doc 1
      freq 3
      pos 5833
      pos 5838
      pos 6849
    doc 4
      freq 1
      pos 950
    doc 11
      freq 10
      pos 1428
      pos 3281
      pos 5289
      pos 5433
      pos 5587
      pos 5753
      pos 5886
      pos 6094
      pos 6428
      pos 7962
    doc 12
      freq 2
      pos 8480
      pos 8994
    doc 17
      freq 1
      pos 654
  term ignored
    doc 0
      freq 2
      pos 6070
      pos 12849
    doc 1
      freq 2
      pos 5356
      pos 6134
    doc 3
      freq 1
      pos 3714
    doc 4
      freq 3
      pos 2222
      pos 2842
      pos 3109
    doc 9
      freq 1
      pos 984
    doc 11
      freq 1
      pos 3267
    doc 17
      freq 1
      pos 1885
  term igp
    doc 6
      freq 1
      pos 2665
  term igrp
    doc 0
      freq 1
      pos 11665
  term ih8jgt5janpjmjuklv9ioifhtsnyi3i863
    doc 11
      freq 1
      pos 10326
  term ihren
    doc 12
      freq 3
      pos 13
      pos 7333
      pos 9442
    doc 14
      freq 1
      pos 5473
    doc 18
      freq 10
      pos 15
      pos 240
      pos 616
      pos 1024
      pos 1379
      pos 1806
      pos 2146
      pos 2175
      pos 2189
      pos 2520
  term ii
    doc 0
      freq 1
      pos 15870
    doc 1
      freq 2
      pos 6551
      pos 6827
    doc 3
      freq 3
      pos 3974
      pos 5103
      pos 5206
    doc 7
      freq 4
      pos 818
      pos 1052
      pos 2228
      pos 2629
  term ii5se6vhbbapjjvmkbzwzqatpp
    doc 10
      freq 1
      pos 6910
  term iiczlblex41scqfxnhwr9uywxevaurlkh37hj0fkm
    doc 11
      freq 1
      pos 10180
  term iih
    doc 0
      freq 20
      pos 776
      pos 795
      pos 814
      pos 6541
      pos 6854
      pos 8466
      pos 9273
      pos 9392
      pos 9424
      pos 9470
      pos 9545
      pos 9579
      pos 9623
      pos 9653
      pos 9730
      pos 9768
      pos 9816
      pos 9848
      pos 9879
      pos 9930
  term iii
    doc 1
      freq 2
      pos 6591
      pos 6867
    doc 3
      freq 1
      pos 3990
    doc 7
      freq 2
      pos 832
      pos 2242
  term ijkvafrau2f
    doc 11
      freq 1
      pos 10105
  term ik0ywvkzhkv9mj8uexqkmvbnvq37cd
    doc 11
      freq 1
      pos 3803
  term ilcnufbu3e5fg
    doc 11
      freq 1
      pos 10380
  term iljitsch
    doc 12
      freq 1
      pos 6808
  term illegal
    doc 0
      freq 1
      pos 705
    doc 1
      freq 3
      pos 2350
      pos 6343
      pos 7834
    doc 11
      freq 2
      pos 5410
      pos 5558
  term illegitimat
    doc 10
      freq 2
      pos 9338
      pos 10150
  term illustrat
    doc 10
      freq 1
      pos 5949
  term illustrates
    doc 1
      freq 1
      pos 7086
    doc 3
      freq 1
      pos 2778
  term illustrativ
    doc 10
      freq 1
      pos 6096
    doc 14
      freq 1
      pos 1959
  term ilmtsbmnvvahjp9u8mkw1f8g
    doc 11
      freq 1
      pos 9902
  term ilya
    doc 11
      freq 1
      pos 9601
  term images
    doc 7
      freq 2
      pos 733
      pos 2070
  term imagin
    doc 10
      freq 1
      pos 1794
  term imap
    doc 12
      freq 3
      pos 2157
      pos 2180
      pos 2203
    doc 16
      freq 46
      pos 23
      pos 96
      pos 109
      pos 169
      pos 185
      pos 255
      pos 264
      pos 340
      pos 379
      pos 535
      pos 669
      pos 713
      pos 836
      pos 859
      pos 872
      pos 878
      pos 885
      pos 910
      pos 922
      pos 956
      pos 984
      pos 1007
      pos 1027
      pos 1180
      pos 1187
      pos 1315
      pos 1338
      pos 1440
      pos 1443
      pos 1459
      pos 1469
      pos 1570
      pos 1622
      pos 1631
      pos 1634
      pos 1671
      pos 1689
      pos 1857
      pos 2115
      pos 2252
      pos 2514
      pos 2538
      pos 2552
      pos 2598
      pos 2643
      pos 2683
  term imap.example.com
    doc 12
      freq 1
      pos 2201
  term imap4
    doc 7
      freq 1
      pos 2601
    doc 16
      freq 3
      pos 1641
      pos 1664
      pos 2630
  term imapurl
    doc 16
      freq 1
      pos 1558
  term imbalanc
    doc 6
      freq 1
      pos 1322
  term img
    doc 13
      freq 276
      pos 90
      pos 109
      pos 247
      pos 250
      pos 255
      pos 302
      pos 310
      pos 594
      pos 670
      pos 708
      pos 733
      pos 767
      pos 798
      pos 845
      pos 867
      pos 901
      pos 953
      pos 976
      pos 1043
      pos 1059
      pos 1097
      pos 1100
      pos 1130
      pos 1218
      pos 1219
      pos 1233
      pos 1239
      pos 1244
      pos 1258
      pos 1265
      pos 1267
      pos 1278
      pos 1280
      pos 1320
      pos 1326
      pos 1338
      pos 1341
      pos 1349
      pos 1355
      pos 1357
      pos 1360
      pos 1368
      pos 1372
      pos 1374
      pos 1377
      pos 1381
      pos 1389
      pos 1393
      pos 1399
      pos 1401
      pos 1408
      pos 1413
      pos 1417
      pos 1424
      pos 1431
      pos 1436
      pos 1443
      pos 1447
      pos 1450
      pos 1469
      pos 1476
      pos 1482
      pos 1489
      pos 1493
      pos 1502
      pos 1510
      pos 1514
      pos 1518
      pos 1656
      pos 1667
      pos 1671
      pos 1674
      pos 1846
      pos 2306
      pos 2406
      pos 2424
      pos 2468
      pos 2497
      pos 2699
      pos 2712
      pos 2776
      pos 2837
      pos 2852
      pos 2855
      pos 2884
      pos 2914
      pos 3030
      pos 3174
      pos 3195
      pos 3337
      pos 3362
      pos 3413
      pos 3421
      pos 3453
      pos 3489
      pos 3569
      pos 3627
      pos 3630
      pos 3639
      pos 3644
      pos 3649
      pos 3699
      pos 3708
      pos 3713
      pos 3724
      pos 3733
      pos 3743
      pos 3748
      pos 3757
      pos 3765
      pos 3778
      pos 3783
      pos 3791
      pos 3797
      pos 3800
      pos 3804
      pos 3824
      pos 3833
      pos 3883
      pos 3978
      pos 4017
      pos 4030
      pos 4035
      pos 4044
      pos 4060
      pos 4074
      pos 4089
      pos 4151
      pos 4219
      pos 4224
      pos 4229
      pos 4251
      pos 4255
      pos 4317
      pos 4331
      pos 4335
      pos 4338
      pos 4349
      pos 4370
      pos 4385
      pos 4388
      pos 4397
      pos 4416
      pos 4424
      pos 4431
      pos 4448
      pos 4459
      pos 4464
      pos 4474
      pos 4479
      pos 4482
      pos 4494
      pos 4513
      pos 4518
      pos 4522
      pos 4535
      pos 4541
      pos 4544
      pos 4549
      pos 4557
      pos 4568
      pos 4573
      pos 4594
      pos 4598
      pos 4620
      pos 4624
      pos 4636
      pos 4710
      pos 4725
      pos 4730
      pos 4740
      pos 4751
      pos 4756
      pos 4766
      pos 4778
      pos 4786
      pos 4794
      pos 4804
      pos 4816
      pos 4825
      pos 4839
      pos 4850
      pos 4856
      pos 4863
      pos 4886
      pos 4899
      pos 4964
      pos 4969
      pos 4972
      pos 4977
      pos 5048
      pos 5071
      pos 5084
      pos 5109
      pos 5121
      pos 5128
      pos 5133
      pos 5140
      pos 5162
      pos 5181
      pos 5184
      pos 5190
      pos 5239
      pos 5278
      pos 5313
      pos 5392
      pos 5410
      pos 5432
      pos 5542
      pos 5552
      pos 5575
      pos 5594
      pos 5611
      pos 5615
      pos 5620
      pos 5668
      pos 5679
      pos 5681
      pos 5688
      pos 5714
      pos 5743
      pos 5764
      pos 5785
      pos 5789
      pos 5827
      pos 5844
      pos 5867
      pos 5884
      pos 5910
      pos 5915
      pos 5938
      pos 5951
      pos 5961
      pos 5976
      pos 5994
      pos 6021
      pos 6024
      pos 6075
      pos 6087
      pos 6091
      pos 6096
      pos 6128
      pos 6141
      pos 6151
      pos 6167
      pos 6210
      pos 6227
      pos 6250
      pos 6262
      pos 6274
      pos 6283
      pos 6293
      pos 6304
      pos 6316
      pos 6319
      pos 6348
      pos 6369
      pos 6376
      pos 6385
      pos 6400
      pos 6409
      pos 6431
      pos 6452
      pos 6458
      pos 6473
      pos 6487
      pos 6492
      pos 6497
      pos 6501
      pos 6519
      pos 6532
      pos 6549
      pos 6609
      pos 6614
      pos 6644
      pos 6875
  term imgs
    doc 13
      freq 48
      pos 36
      pos 129
      pos 164
      pos 287
      pos 322
      pos 359
      pos 573
      pos 642
      pos 763
      pos 1051
      pos 1090
      pos 1145
      pos 1157
      pos 1466
      pos 1530
      pos 1825
      pos 1862
      pos 2005
      pos 2177
      pos 2569
      pos 2733
      pos 2796
      pos 2832
      pos 2940
      pos 3253
      pos 3276
      pos 3307
      pos 3313
      pos 3351
      pos 3668
      pos 3969
      pos 4022
      pos 4304
      pos 4374
      pos 4679
      pos 5024
      pos 5261
      pos 5386
      pos 5695
      pos 5736
      pos 5752
      pos 5783
      pos 6015
      pos 6139
      pos 6337
      pos 6659
      pos 6949
      pos 7089
  term immatur
    doc 7
      freq 2
      pos 171
      pos 1440
  term immediat
    doc 12
      freq 2
      pos 3559
      pos 6695
    doc 13
      freq 1
      pos 4176
    doc 14
      freq 8
      pos 233
      pos 242
      pos 400
      pos 439
      pos 590
      pos 598
      pos 2955
      pos 4147
  term immediately
    doc 0
      freq 1
      pos 2193
    doc 1
      freq 1
      pos 887
    doc 4
      freq 1
      pos 563
    doc 10
      freq 1
      pos 997
    doc 12
      freq 1
      pos 3737
    doc 13
      freq 2
      pos 4583
      pos 4992
    doc 18
      freq 2
      pos 1234
      pos 1873
  term impact
    doc 14
      freq 1
      pos 2131
    doc 15
      freq 1
      pos 2175
    doc 16
      freq 1
      pos 366
  term impair
    doc 12
      freq 1
      pos 1927
  term impairment
    doc 6
      freq 1
      pos 2573
  term impairments
    doc 6
      freq 5
      pos 807
      pos 869
      pos 1017
      pos 1036
      pos 2738
  term impending
    doc 6
      freq 2
      pos 993
      pos 2697
  term imperfect
    doc 13
      freq 1
      pos 6593
    doc 18
      freq 1
      pos 1559
  term impersonation
    doc 10
      freq 8
      pos 823
      pos 850
      pos 878
      pos 8345
      pos 9638
      pos 9795
      pos 9873
      pos 10179
  term impersonations
    doc 10
      freq 1
      pos 9373
  term impersonator
    doc 10
      freq 2
      pos 9404
      pos 9715
  term impersonators
    doc 10
      freq 1
      pos 9693
  term impetus
    doc 10
      freq 1
      pos 9462
  term implement
    doc 0
      freq 1
      pos 17512
    doc 1
      freq 2
      pos 4262
      pos 9893
    doc 2
      freq 5
      pos 4160
      pos 5840
      pos 5868
      pos 5921
      pos 6690
    doc 3
      freq 1
      pos 6242
    doc 4
      freq 5
      pos 3664
      pos 3683
      pos 3830
      pos 3849
      pos 6397
    doc 5
      freq 1
      pos 4727
    doc 6
      freq 1
      pos 3527
    doc 7
      freq 1
      pos 3232
    doc 8
      freq 1
      pos 2449
    doc 9
      freq 1
      pos 2094
    doc 10
      freq 3
      pos 4360
      pos 11064
      pos 13755
    doc 11
      freq 1
      pos 10916
    doc 12
      freq 3
      pos 3397
      pos 4129
      pos 9766
    doc 13
      freq 1
      pos 7381
    doc 14
      freq 1
      pos 5847
    doc 15
      freq 1
      pos 4366
    doc 16
      freq 1
      pos 2977
    doc 17
      freq 3
      pos 1468
      pos 1912
      pos 2701
    doc 18
      freq 2
      pos 1761
      pos 2489
    skipList 
      level 0
        skipDoc 7
        skipDocFP 1113732
        impacts 
          impact 
            freq 1
            norm 100
          impact 
            freq 5
            norm 108
        impactsEnd 
        skipDoc 15
        skipDocFP 1114172
        impacts 
          impact 
            freq 1
            norm 95
          impact 
            freq 3
            norm 113
        impactsEnd 
  term implementation
    doc 0
      freq 8
      pos 2148
      pos 2425
      pos 4990
      pos 5095
      pos 5358
      pos 6114
      pos 14782
      pos 17360
    doc 1
      freq 2
      pos 2030
      pos 9741
    doc 2
      freq 3
      pos 1593
      pos 3618
      pos 6538
    doc 3
      freq 2
      pos 5311
      pos 6090
    doc 4
      freq 5
      pos 1963
      pos 1994
      pos 2002
      pos 4372
      pos 6245
    doc 5
      freq 2
      pos 4296
      pos 4575
    doc 6
      freq 2
      pos 166
      pos 3375
    doc 7
      freq 5
      pos 576
      pos 1757
      pos 1924
      pos 2441
      pos 3080
    doc 8
      freq 1
      pos 2297
    doc 9
      freq 1
      pos 1942
    doc 10
      freq 2
      pos 4034
      pos 13603
    doc 11
      freq 4
      pos 94
      pos 7681
      pos 9370
      pos 10764
    doc 12
      freq 8
      pos 89
      pos 213
      pos 651
      pos 1618
      pos 3620
      pos 8695
      pos 9143
      pos 9614
    doc 13
      freq 1
      pos 7229
    doc 14
      freq 2
      pos 5381
      pos 5695
    doc 15
      freq 2
      pos 3517
      pos 4214
    doc 16
      freq 1
      pos 2825
    doc 17
      freq 3
      pos 1144
      pos 1653
      pos 2549
    doc 18
      freq 1
      pos 2337
    skipList 
      level 0
        skipDoc 7
        skipDocFP 1115151
        impacts 
          impact 
            freq 5
            norm 100
          impact 
            freq 8
            norm 120
        impactsEnd 
        skipDoc 15
        skipDocFP 1115770
        impacts 
          impact 
            freq 1
            norm 95
          impact 
            freq 2
            norm 104
          impact 
            freq 8
            norm 113
        impactsEnd 
  term implementation's
    doc 11
      freq 2
      pos 7012
      pos 7159
  term implementations
    doc 0
      freq 3
      pos 2428
      pos 6104
      pos 12973
    doc 1
      freq 1
      pos 1888
    doc 2
      freq 1
      pos 5083
    doc 3
      freq 3
      pos 3361
      pos 3529
      pos 3554
    doc 4
      freq 4
      pos 927
      pos 948
      pos 1347
      pos 2692
    doc 6
      freq 3
      pos 419
      pos 1464
      pos 3175
    doc 10
      freq 12
      pos 537
      pos 710
      pos 3937
      pos 4646
      pos 5478
      pos 5591
      pos 5978
      pos 6020
      pos 6102
      pos 7623
      pos 8490
      pos 8527
    doc 11
      freq 4
      pos 1600
      pos 2324
      pos 7321
      pos 9351
    doc 12
      freq 13
      pos 1694
      pos 1757
      pos 1844
      pos 8521
      pos 8530
      pos 8553
      pos 8674
      pos 8803
      pos 8807
      pos 9312
      pos 9346
      pos 9370
      pos 9392
    doc 13
      freq 1
      pos 3907
    doc 14
      freq 1
      pos 2152
    doc 15
      freq 1
      pos 1709
    skipList 
      level 0
        skipDoc 11
        skipDocFP 1116999
        impacts 
          impact 
            freq 3
            norm 101
          impact 
            freq 4
            norm 108
          impact 
            freq 12
            norm 116
        impactsEnd 
  term implemented
    doc 0
      freq 3
      pos 2205
      pos 2308
      pos 14770
    doc 1
      freq 4
      pos 5009
      pos 5487
      pos 7142
      pos 8638
    doc 2
      freq 1
      pos 3837
    doc 4
      freq 2
      pos 524
      pos 1160
    doc 10
      freq 1
      pos 11301
    doc 11
      freq 1
      pos 6832
  term implementer
    doc 7
      freq 1
      pos 570
  term implementers
    doc 0
      freq 5
      pos 3614
      pos 4130
      pos 10971
      pos 16720
      pos 17462
    doc 1
      freq 1
      pos 9843
    doc 2
      freq 1
      pos 6640
    doc 3
      freq 1
      pos 6192
    doc 4
      freq 1
      pos 6347
    doc 5
      freq 1
      pos 4677
    doc 6
      freq 1
      pos 3477
    doc 7
      freq 1
      pos 3182
    doc 8
      freq 1
      pos 2399
    doc 9
      freq 1
      pos 2044
    doc 10
      freq 3
      pos 3702
      pos 5963
      pos 13705
    doc 11
      freq 1
      pos 10866
    doc 12
      freq 1
      pos 9716
    doc 13
      freq 1
      pos 7331
    doc 14
      freq 1
      pos 5797
    doc 15
      freq 1
      pos 4316
    doc 16
      freq 1
      pos 2927
    doc 17
      freq 2
      pos 1854
      pos 2651
    doc 18
      freq 1
      pos 2439
    skipList 
      level 0
        skipDoc 7
        skipDocFP 1118685
        impacts 
          impact 
            freq 1
            norm 100
          impact 
            freq 5
            norm 120
        impactsEnd 
        skipDoc 15
        skipDocFP 1119052
        impacts 
          impact 
            freq 1
            norm 95
          impact 
            freq 3
            norm 116
        impactsEnd 
  term implementing
    doc 1
      freq 2
      pos 5585
      pos 7266
    doc 4
      freq 1
      pos 1888
    doc 5
      freq 1
      pos 1215
    doc 6
      freq 1
      pos 2997
    doc 11
      freq 1
      pos 6644
    doc 15
      freq 2
      pos 539
      pos 551
    doc 16
      freq 1
      pos 1047
  term implementor
    doc 11
      freq 1
      pos 2435
  term implementors
    doc 11
      freq 1
      pos 4608
    doc 14
      freq 2
      pos 419
      pos 1843
  term implements
    doc 12
      freq 1
      pos 3259
    doc 16
      freq 1
      pos 1185
  term implication
    doc 12
      freq 1
      pos 7990
    doc 13
      freq 1
      pos 4170
  term implications
    doc 2
      freq 1
      pos 2341
    doc 7
      freq 1
      pos 1167
    doc 10
      freq 2
      pos 8158
      pos 8204
    doc 12
      freq 3
      pos 3444
      pos 6086
      pos 8685
  term implicit
    doc 0
      freq 1
      pos 10298
    doc 17
      freq 1
      pos 2194
  term implied
    doc 0
      freq 2
      pos 17300
      pos 17322
    doc 1
      freq 2
      pos 9681
      pos 9703
    doc 2
      freq 2
      pos 6478
      pos 6500
    doc 3
      freq 2
      pos 6030
      pos 6052
    doc 4
      freq 2
      pos 6185
      pos 6207
    doc 5
      freq 2
      pos 4515
      pos 4537
    doc 6
      freq 2
      pos 3315
      pos 3337
    doc 7
      freq 2
      pos 3020
      pos 3042
    doc 8
      freq 2
      pos 2237
      pos 2259
    doc 9
      freq 2
      pos 1882
      pos 1904
    doc 10
      freq 2
      pos 13543
      pos 13565
    doc 11
      freq 2
      pos 10704
      pos 10726
    doc 12
      freq 2
      pos 9554
      pos 9576
    doc 13
      freq 2
      pos 7169
      pos 7191
    doc 14
      freq 2
      pos 5635
      pos 5657
    doc 15
      freq 2
      pos 4154
      pos 4176
    doc 16
      freq 2
      pos 2765
      pos 2787
    doc 17
      freq 2
      pos 2489
      pos 2511
    doc 18
      freq 2
      pos 2277
      pos 2299
    skipList 
      level 0
        skipDoc 7
        skipDocFP 1120956
        impacts 
          impact 
            freq 2
            norm 100
        impactsEnd 
        skipDoc 15
        skipDocFP 1121382
        impacts 
          impact 
            freq 2
            norm 95
        impactsEnd 
  term implies
    doc 11
      freq 1
      pos 6288
    doc 12
      freq 2
      pos 6257
      pos 7954
    doc 13
      freq 1
      pos 2333
  term imply
    doc 11
      freq 1
      pos 1799
    doc 15
      freq 1
      pos 3297
  term implying
    doc 12
      freq 1
      pos 6381
  term importanc
    doc 13
      freq 1
      pos 3910
  term important
    doc 1
      freq 4
      pos 7382
      pos 8110
      pos 8447
      pos 8687
    doc 5
      freq 1
      pos 970
    doc 6
      freq 1
      pos 2133
    doc 10
      freq 3
      pos 9082
      pos 9449
      pos 9625
    doc 11
      freq 2
      pos 4194
      pos 6079
    doc 12
      freq 3
      pos 2720
      pos 2753
      pos 4441
    doc 13
      freq 5
      pos 2093
      pos 2286
      pos 3887
      pos 3948
      pos 4991
    doc 15
      freq 3
      pos 141
      pos 2010
      pos 3136
    doc 17
      freq 1
      pos 1930
    skipList 
      level 0
        skipDoc 15
        skipDocFP 1122650
        impacts 
          impact 
            freq 1
            norm 101
          impact 
            freq 3
            norm 104
          impact 
            freq 5
            norm 109
        impactsEnd 
  term imported
    doc 0
      freq 1
      pos 425
  term imports
    doc 0
      freq 3
      pos 387
      pos 416
      pos 1010
    doc 17
      freq 2
      pos 2199
      pos 2200
  term imposed
    doc 6
      freq 1
      pos 811
  term imposes
    doc 1
      freq 1
      pos 7593
  term imposition
    doc 1
      freq 4
      pos 7454
      pos 7547
      pos 7591
      pos 7676
  term impossibl
    doc 1
      freq 1
      pos 2802
    doc 5
      freq 1
      pos 3114
    doc 10
      freq 2
      pos 9334
      pos 11141
  term impracticabl
    doc 14
      freq 1
      pos 377
  term impractical
    doc 10
      freq 1
      pos 1410
    doc 18
      freq 1
      pos 339
  term imprecis
    doc 13
      freq 1
      pos 1243
  term imprimatur
    doc 10
      freq 1
      pos 1335
  term improbabl
    doc 14
      freq 1
      pos 2300
  term improperly
    doc 11
      freq 1
      pos 713
  term improv
    doc 2
      freq 1
      pos 338
    doc 6
      freq 1
      pos 326
  term improvement
    doc 14
      freq 1
      pos 51
  term improvements
    doc 0
      freq 1
      pos 50
    doc 1
      freq 1
      pos 67
    doc 3
      freq 1
      pos 61
    doc 4
      freq 1
      pos 63
    doc 5
      freq 1
      pos 47
    doc 8
      freq 1
      pos 51
    doc 9
      freq 1
      pos 49
    doc 10
      freq 1
      pos 52
    doc 12
      freq 1
      pos 6777
    doc 16
      freq 1
      pos 48
    doc 17
      freq 1
      pos 45
    doc 18
      freq 1
      pos 54
    skipList 
      level 0
        skipDoc 10
        skipDocFP 1124574
        impacts 
          impact 
            freq 1
            norm 95
        impactsEnd 
  term improves
    doc 13
      freq 1
      pos 2150
  term impunity
    doc 10
      freq 1
      pos 9864
  term inability
    doc 4
      freq 1
      pos 2471
  term inactiv
    doc 0
      freq 3
      pos 5938
      pos 6013
      pos 6064
    doc 2
      freq 1
      pos 5167
  term inadequat
    doc 2
      freq 1
      pos 4177
    doc 10
      freq 1
      pos 102
  term inadvertent
    doc 9
      freq 1
      pos 1044
  term inappropriat
    doc 2
      freq 1
      pos 1643
    doc 6
      freq 1
      pos 137
    doc 10
      freq 3
      pos 2801
      pos 3108
      pos 3610
    doc 12
      freq 2
      pos 4029
      pos 4053
  term inappropriately
    doc 12
      freq 1
      pos 9219
  term inband
    doc 5
      freq 3
      pos 843
      pos 2252
      pos 2537
  term inbound
    doc 10
      freq 2
      pos 10591
      pos 10676
  term inbox
    doc 16
      freq 4
      pos 2400
      pos 2417
      pos 2436
      pos 2456
  term inc
    doc 1
      freq 9
      pos 17
      pos 29
      pos 9190
      pos 9204
      pos 9235
      pos 9384
      pos 9509
      pos 9562
      pos 9576
    doc 3
      freq 5
      pos 17
      pos 4770
      pos 4949
      pos 5874
      pos 5927
    doc 4
      freq 1
      pos 6062
    doc 6
      freq 3
      pos 3103
      pos 3184
      pos 3202
    doc 8
      freq 2
      pos 11
      pos 2133
    doc 10
      freq 1
      pos 13408
    doc 18
      freq 2
      pos 10
      pos 2162
  term incapabl
    doc 3
      freq 1
      pos 2039
  term incident
    doc 17
      freq 1
      pos 1492
  term incl
    doc 5
      freq 2
      pos 2393
      pos 2402
  term includ
    doc 0
      freq 4
      pos 1174
      pos 5914
      pos 15868
      pos 16754
    doc 1
      freq 6
      pos 3348
      pos 5347
      pos 5642
      pos 5785
      pos 7338
      pos 7358
    doc 2
      freq 1
      pos 3926
    doc 3
      freq 3
      pos 993
      pos 2248
      pos 3536
    doc 4
      freq 1
      pos 1439
    doc 6
      freq 1
      pos 2124
    doc 10
      freq 4
      pos 2571
      pos 3443
      pos 5243
      pos 5256
    doc 11
      freq 10
      pos 2027
      pos 2731
      pos 4866
      pos 5301
      pos 5605
      pos 5771
      pos 7940
      pos 8685
      pos 8794
      pos 8899
    doc 12
      freq 4
      pos 128
      pos 1521
      pos 4059
      pos 4646
    doc 13
      freq 3
      pos 2311
      pos 2833
      pos 5494
    doc 16
      freq 2
      pos 199
      pos 492
    doc 17
      freq 1
      pos 343
    doc 18
      freq 1
      pos 2004
    skipList 
      level 0
        skipDoc 11
        skipDocFP 1126843
        impacts 
          impact 
            freq 1
            norm 101
          impact 
            freq 3
            norm 107
          impact 
            freq 6
            norm 113
          impact 
            freq 10
            norm 114
        impactsEnd 
  term included
    doc 0
      freq 4
      pos 943
      pos 1387
      pos 1453
      pos 14123
    doc 1
      freq 3
      pos 5558
      pos 5760
      pos 7234
    doc 2
      freq 8
      pos 239
      pos 331
      pos 3701
      pos 3764
      pos 4771
      pos 5285
      pos 5812
      pos 6192
    doc 6
      freq 2
      pos 1461
      pos 2672
    doc 8
      freq 1
      pos 101
    doc 9
      freq 1
      pos 988
    doc 10
      freq 4
      pos 8713
      pos 8804
      pos 9427
      pos 12295
    doc 12
      freq 4
      pos 1898
      pos 4651
      pos 4906
      pos 8133
    doc 13
      freq 1
      pos 502
    doc 15
      freq 1
      pos 2934
    doc 17
      freq 6
      pos 443
      pos 565
      pos 1224
      pos 1302
      pos 1319
      pos 1351
    skipList 
      level 0
        skipDoc 12
        skipDocFP 1128121
        impacts 
          impact 
            freq 1
            norm 95
          impact 
            freq 2
            norm 101
          impact 
            freq 8
            norm 108
        impactsEnd 
  term includes
    doc 0
      freq 10
      pos 496
      pos 519
      pos 7865
      pos 13100
      pos 13214
      pos 13300
      pos 13431
      pos 13517
      pos 13621
      pos 13711
    doc 1
      freq 1
      pos 607
    doc 2
      freq 2
      pos 474
      pos 495
    doc 3
      freq 1
      pos 972
    doc 4
      freq 1
      pos 4266
    doc 5
      freq 1
      pos 3554
    doc 10
      freq 2
      pos 5229
      pos 12213
    doc 12
      freq 1
      pos 1261
    doc 15
      freq 1
      pos 2808
    doc 17
      freq 3
      pos 550
      pos 1195
      pos 1712
    skipList 
      level 0
        skipDoc 12
        skipDocFP 1129197
        impacts 
          impact 
            freq 1
            norm 104
          impact 
            freq 2
            norm 108
          impact 
            freq 10
            norm 120
        impactsEnd 
  term including
    doc 0
      freq 2
      pos 16735
      pos 17301
    doc 1
      freq 4
      pos 2242
      pos 6108
      pos 8198
      pos 9682
    doc 2
      freq 7
      pos 359
      pos 1374
      pos 4797
      pos 4866
      pos 5710
      pos 6031
      pos 6479
    doc 3
      freq 6
      pos 519
      pos 725
      pos 728
      pos 1054
      pos 3312
      pos 6031
    doc 4
      freq 2
      pos 4824
      pos 6186
    doc 5
      freq 3
      pos 3782
      pos 3998
      pos 4516
    doc 6
      freq 3
      pos 776
      pos 2127
      pos 3316
    doc 7
      freq 1
      pos 3021
    doc 8
      freq 3
      pos 969
      pos 1109
      pos 2238
    doc 9
      freq 1
      pos 1883
    doc 10
      freq 9
      pos 528
      pos 1913
      pos 4074
      pos 4474
      pos 4541
      pos 8301
      pos 8324
      pos 12310
      pos 13544
    doc 11
      freq 2
      pos 1678
      pos 10705
    doc 12
      freq 3
      pos 78
      pos 9355
      pos 9555
    doc 13
      freq 6
      pos 376
      pos 639
      pos 944
      pos 1093
      pos 2322
      pos 7170
    doc 14
      freq 3
      pos 2381
      pos 2673
      pos 5636
    doc 15
      freq 2
      pos 3706
      pos 4155
    doc 16
      freq 1
      pos 2766
    doc 17
      freq 1
      pos 2490
    doc 18
      freq 2
      pos 466
      pos 2278
    skipList 
      level 0
        skipDoc 7
        skipDocFP 1130080
        impacts 
          impact 
            freq 1
            norm 100
          impact 
            freq 3
            norm 101
          impact 
            freq 6
            norm 107
          impact 
            freq 7
            norm 108
        impactsEnd 
        skipDoc 15
        skipDocFP 1130681
        impacts 
          impact 
            freq 1
            norm 95
          impact 
            freq 3
            norm 97
          impact 
            freq 6
            norm 109
          impact 
            freq 9
            norm 116
        impactsEnd 
  term inclusion
    doc 4
      freq 2
      pos 1018
      pos 1309
    doc 10
      freq 1
      pos 5298
  term incoming
    doc 1
      freq 3
      pos 2872
      pos 8178
      pos 8477
    doc 2
      freq 1
      pos 533
    doc 4
      freq 2
      pos 2975
      pos 3212
  term incompatibl
    doc 1
      freq 2
      pos 2358
      pos 7846
    doc 10
      freq 1
      pos 1525
    doc 15
      freq 1
      pos 2048
  term incomplet
    doc 12
      freq 1
      pos 3005
  term inconsistencies
    doc 13
      freq 1
      pos 5027
    doc 15
      freq 2
      pos 1918
      pos 2020
  term inconsistency
    doc 13
      freq 3
      pos 3776
      pos 4948
      pos 4956
  term inconsistent
    doc 7
      freq 1
      pos 1576
    doc 12
      freq 1
      pos 9006
    doc 13
      freq 1
      pos 6604
  term inconsistentnam
    doc 0
      freq 3
      pos 3866
      pos 4366
      pos 11230
  term inconsistentvalu
    doc 0
      freq 4
      pos 3125
      pos 3297
      pos 5333
      pos 6900
  term incorporated
    doc 10
      freq 1
      pos 9534
    doc 16
      freq 2
      pos 10
      pos 2654
  term incorporating
    doc 2
      freq 1
      pos 959
  term incorrect
    doc 0
      freq 1
      pos 13511
    doc 11
      freq 1
      pos 663
  term incorrectly
    doc 18
      freq 1
      pos 1947
  term increas
    doc 0
      freq 1
      pos 13380
    doc 3
      freq 1
      pos 3447
    doc 14
      freq 1
      pos 2822
  term increased
    doc 3
      freq 1
      pos 1668
    doc 13
      freq 3
      pos 537
      pos 1684
      pos 1692
    doc 18
      freq 2
      pos 468
      pos 477
  term increases
    doc 13
      freq 1
      pos 2159
  term increasing
    doc 0
      freq 1
      pos 16501
    doc 2
      freq 1
      pos 1734
    doc 6
      freq 2
      pos 508
      pos 2485
  term increasingly
    doc 2
      freq 2
      pos 1181
      pos 1947
  term increment
    doc 14
      freq 3
      pos 999
      pos 1651
      pos 1982
    doc 18
      freq 3
      pos 1278
      pos 1819
      pos 1844
  term incremental
    doc 7
      freq 1
      pos 2863
  term incremented
    doc 14
      freq 1
      pos 4528
  term incrementing
    doc 14
      freq 2
      pos 1945
      pos 2218
  term incur
    doc 12
      freq 1
      pos 3511
  term incurred
    doc 4
      freq 1
      pos 1831
    doc 12
      freq 1
      pos 3046
  term incurring
    doc 12
      freq 1
      pos 3635
    doc 14
      freq 2
      pos 2690
      pos 2819
  term indeed
    doc 0
      freq 1
      pos 16874
    doc 10
      freq 1
      pos 10445
    doc 11
      freq 2
      pos 1910
      pos 1989
  term indefinitely
    doc 6
      freq 1
      pos 1101
  term independenc
    doc 12
      freq 3
      pos 160
      pos 872
      pos 8761
    doc 13
      freq 3
      pos 245
      pos 3625
      pos 5179
  term independent
    doc 0
      freq 4
      pos 4995
      pos 5005
      pos 12965
      pos 17395
    doc 1
      freq 1
      pos 9776
    doc 2
      freq 3
      pos 3698
      pos 4151
      pos 6573
    doc 3
      freq 1
      pos 6125
    doc 4
      freq 1
      pos 6280
    doc 5
      freq 1
      pos 4610
    doc 6
      freq 2
      pos 815
      pos 3410
    doc 7
      freq 1
      pos 3115
    doc 8
      freq 1
      pos 2332
    doc 9
      freq 1
      pos 1977
    doc 10
      freq 1
      pos 13638
    doc 11
      freq 1
      pos 10799
    doc 12
      freq 3
      pos 916
      pos 1059
      pos 9649
    doc 13
      freq 4
      pos 1116
      pos 5282
      pos 6696
      pos 7264
    doc 14
      freq 1
      pos 5730
    doc 15
      freq 1
      pos 4249
    doc 16
      freq 1
      pos 2860
    doc 17
      freq 1
      pos 2584
    doc 18
      freq 1
      pos 2372
    skipList 
      level 0
        skipDoc 7
        skipDocFP 1134995
        impacts 
          impact 
            freq 1
            norm 100
          impact 
            freq 2
            norm 101
          impact 
            freq 3
            norm 108
          impact 
            freq 4
            norm 120
        impactsEnd 
        skipDoc 15
        skipDocFP 1135390
        impacts 
          impact 
            freq 1
            norm 95
          impact 
            freq 4
            norm 109
        impactsEnd 
  term independently
    doc 1
      freq 2
      pos 1671
      pos 2859
    doc 2
      freq 1
      pos 4225
  term index
    doc 0
      freq 47
      pos 618
      pos 3163
      pos 3195
      pos 3444
      pos 3660
      pos 3795
      pos 3823
      pos 3847
      pos 3859
      pos 4176
      pos 4307
      pos 4323
      pos 4347
      pos 4359
      pos 4507
      pos 4696
      pos 5292
      pos 5463
      pos 5522
      pos 5553
      pos 6331
      pos 7239
      pos 7795
      pos 8336
      pos 8879
      pos 9481
      pos 9508
      pos 9664
      pos 9693
      pos 9890
      pos 10027
      pos 11030
      pos 11171
      pos 11187
      pos 11211
      pos 11223
      pos 11256
      pos 11761
      pos 12100
      pos 12136
      pos 12147
      pos 12155
      pos 13102
      pos 13303
      pos 14276
      pos 14406
      pos 14572
    doc 1
      freq 3
      pos 2660
      pos 2665
      pos 4155
    doc 6
      freq 15
      pos 23
      pos 182
      pos 293
      pos 540
      pos 746
      pos 912
      pos 1136
      pos 1143
      pos 1617
      pos 2032
      pos 2155
      pos 2346
      pos 2762
      pos 3039
      pos 3229
    doc 7
      freq 2
      pos 1121
      pos 2780
    doc 11
      freq 1
      pos 4645
  term indexed
    doc 10
      freq 1
      pos 3987
  term indexing
    doc 13
      freq 1
      pos 2821
  term indexinteger
    doc 0
      freq 3
      pos 1050
      pos 5482
      pos 5513
  term indexintegernextfre
    doc 0
      freq 2
      pos 1051
      pos 5229
  term india
    doc 3
      freq 1
      pos 4808
  term indicat
    doc 0
      freq 1
      pos 16951
    doc 1
      freq 5
      pos 2111
      pos 5036
      pos 5153
      pos 5315
      pos 8904
    doc 3
      freq 3
      pos 3688
      pos 3762
      pos 4502
    doc 4
      freq 2
      pos 3491
      pos 5277
    doc 5
      freq 3
      pos 1256
      pos 1351
      pos 4132
    doc 6
      freq 4
      pos 991
      pos 1627
      pos 2304
      pos 2480
    doc 7
      freq 2
      pos 1528
      pos 1746
    doc 8
      freq 1
      pos 1772
    doc 9
      freq 1
      pos 1675
    doc 10
      freq 5
      pos 704
      pos 3100
      pos 8515
      pos 11587
      pos 13126
    doc 12
      freq 3
      pos 3868
      pos 3923
      pos 4590
    doc 13
      freq 1
      pos 6745
    doc 16
      freq 1
      pos 2275
    doc 17
      freq 1
      pos 2037
    doc 18
      freq 1
      pos 2136
    skipList 
      level 0
        skipDoc 8
        skipDocFP 1138046
        impacts 
          impact 
            freq 1
            norm 97
          impact 
            freq 2
            norm 100
          impact 
            freq 4
            norm 101
          impact 
            freq 5
            norm 113
        impactsEnd 
  term indicated
    doc 10
      freq 2
      pos 2042
      pos 5627
    doc 16
      freq 3
      pos 748
      pos 764
      pos 1103
    doc 17
      freq 2
      pos 698
      pos 1239
  term indicates
    doc 0
      freq 7
      pos 4884
      pos 4897
      pos 4913
      pos 5564
      pos 5835
      pos 10514
      pos 11540
    doc 4
      freq 2
      pos 630
      pos 3159
    doc 6
      freq 6
      pos 543
      pos 1468
      pos 1601
      pos 2199
      pos 2218
      pos 2694
    doc 10
      freq 1
      pos 8350
    doc 11
      freq 2
      pos 7024
      pos 8972
    doc 17
      freq 3
      pos 310
      pos 603
      pos 671
  term indicating
    doc 0
      freq 1
      pos 10630
    doc 1
      freq 1
      pos 6144
    doc 3
      freq 1
      pos 2024
    doc 4
      freq 1
      pos 3421
    doc 11
      freq 1
      pos 9020
  term indication
    doc 1
      freq 1
      pos 5194
    doc 6
      freq 5
      pos 227
      pos 936
      pos 1375
      pos 1560
      pos 2276
    doc 12
      freq 1
      pos 3899
  term indications
    doc 2
      freq 1
      pos 2344
    doc 3
      freq 1
      pos 1588
    doc 6
      freq 1
      pos 2286
  term indicator
    doc 6
      freq 3
      pos 196
      pos 919
      pos 2706
    doc 8
      freq 2
      pos 1075
      pos 1081
  term indices
    doc 9
      freq 2
      pos 968
      pos 980
  term indirection
    doc 12
      freq 1
      pos 2239
  term individual
    doc 1
      freq 5
      pos 1314
      pos 3262
      pos 3492
      pos 3497
      pos 8126
    doc 2
      freq 1
      pos 722
    doc 3
      freq 1
      pos 3291
    doc 7
      freq 1
      pos 1743
    doc 8
      freq 4
      pos 143
      pos 1137
      pos 1149
      pos 1292
    doc 10
      freq 1
      pos 8319
    doc 13
      freq 6
      pos 2294
      pos 2904
      pos 3270
      pos 3383
      pos 6030
      pos 6100
  term individually
    doc 1
      freq 1
      pos 5151
    doc 13
      freq 3
      pos 1262
      pos 5906
      pos 5934
  term individuals
    doc 0
      freq 1
      pos 15905
    doc 11
      freq 1
      pos 9547
    doc 15
      freq 1
      pos 3877
    doc 18
      freq 1
      pos 1998
  term induced
    doc 6
      freq 3
      pos 659
      pos 1016
      pos 1504
    doc 11
      freq 1
      pos 4200
  term inefficient
    doc 13
      freq 1
      pos 5039
  term ineoquest
    doc 6
      freq 3
      pos 9
      pos 3101
      pos 3182
  term ineoquest.com
    doc 6
      freq 1
      pos 3197
  term inet
    doc 0
      freq 2
      pos 410
      pos 1065
  term inetaddress
    doc 0
      freq 11
      pos 1062
      pos 3683
      pos 3719
      pos 4187
      pos 4231
      pos 9677
      pos 9754
      pos 11043
      pos 11051
      pos 11105
      pos 11313
  term inetaddressprefixlength
    doc 0
      freq 7
      pos 1063
      pos 3685
      pos 3773
      pos 4189
      pos 4285
      pos 11045
      pos 11150
  term inetaddresstyp
    doc 0
      freq 19
      pos 1061
      pos 3681
      pos 3696
      pos 4185
      pos 4208
      pos 9675
      pos 9713
      pos 11041
      pos 11049
      pos 11072
      pos 11279
      pos 14449
      pos 14473
      pos 14509
      pos 14615
      pos 14639
      pos 14675
      pos 14699
      pos 14723
  term inexhaustibl
    doc 14
      freq 1
      pos 2751
  term inf
    doc 10
      freq 2
      pos 5804
      pos 5835
  term infancy
    doc 15
      freq 1
      pos 3665
  term infeasibl
    doc 10
      freq 1
      pos 10276
    doc 12
      freq 1
      pos 5661
    doc 13
      freq 2
      pos 4181
      pos 5231
  term infer
    doc 1
      freq 3
      pos 1591
      pos 1623
      pos 1649
    doc 11
      freq 3
      pos 5116
      pos 6323
      pos 6546
  term inferenc
    doc 11
      freq 1
      pos 5136
  term info
    doc 0
      freq 1
      pos 1089
    doc 1
      freq 3
      pos 2492
      pos 3679
      pos 4292
    doc 10
      freq 60
      pos 155
      pos 236
      pos 326
      pos 347
      pos 352
      pos 2005
      pos 3337
      pos 3341
      pos 3995
      pos 4026
      pos 4050
      pos 4060
      pos 4757
      pos 4775
      pos 4816
      pos 4818
      pos 4821
      pos 4824
      pos 4827
      pos 4832
      pos 4835
      pos 4838
      pos 4841
      pos 4847
      pos 5437
      pos 5446
      pos 5499
      pos 5572
      pos 5607
      pos 5660
      pos 5690
      pos 5726
      pos 5742
      pos 5755
      pos 5824
      pos 5932
      pos 6183
      pos 6659
      pos 6733
      pos 6787
      pos 7374
      pos 9255
      pos 9413
      pos 9890
      pos 10377
      pos 10411
      pos 11171
      pos 11476
      pos 11492
      pos 11532
      pos 11640
      pos 11663
      pos 11730
      pos 11768
      pos 11928
      pos 11939
      pos 11994
      pos 12006
      pos 12019
      pos 12291
  term infocomm
    doc 3
      freq 1
      pos 4799
  term inform
    doc 4
      freq 2
      pos 2594
      pos 4952
  term information
    doc 0
      freq 45
      pos 18
      pos 97
      pos 229
      pos 234
      pos 265
      pos 306
      pos 466
      pos 591
      pos 626
      pos 644
      pos 734
      pos 840
      pos 864
      pos 897
      pos 1127
      pos 4490
      pos 4572
      pos 4642
      pos 4662
      pos 6266
      pos 6286
      pos 8280
      pos 8309
      pos 9949
      pos 10418
      pos 10457
      pos 10642
      pos 10847
      pos 10866
      pos 11387
      pos 11696
      pos 13031
      pos 13067
      pos 13513
      pos 15980
      pos 16170
      pos 16894
      pos 16920
      pos 16932
      pos 17003
      pos 17050
      pos 17262
      pos 17313
      pos 17402
      pos 17518
    doc 1
      freq 17
      pos 817
      pos 1404
      pos 2580
      pos 2826
      pos 2830
      pos 3815
      pos 4342
      pos 4412
      pos 5048
      pos 5505
      pos 5545
      pos 7161
      pos 7221
      pos 9643
      pos 9694
      pos 9783
      pos 9899
    doc 2
      freq 15
      pos 29
      pos 223
      pos 914
      pos 944
      pos 2526
      pos 2530
      pos 2582
      pos 2586
      pos 2623
      pos 2627
      pos 2664
      pos 6440
      pos 6491
      pos 6580
      pos 6696
    doc 3
      freq 8
      pos 4413
      pos 4417
      pos 4544
      pos 4602
      pos 5992
      pos 6043
      pos 6132
      pos 6248
    doc 4
      freq 7
      pos 2889
      pos 4611
      pos 5511
      pos 6147
      pos 6198
      pos 6287
      pos 6403
    doc 5
      freq 14
      pos 704
      pos 717
      pos 741
      pos 1193
      pos 2170
      pos 2525
      pos 3305
      pos 3391
      pos 3581
      pos 3612
      pos 4477
      pos 4528
      pos 4617
      pos 4733
    doc 6
      freq 13
      pos 32
      pos 174
      pos 216
      pos 280
      pos 775
      pos 1011
      pos 2069
      pos 2828
      pos 2847
      pos 3277
      pos 3328
      pos 3417
      pos 3533
    doc 7
      freq 15
      pos 43
      pos 722
      pos 970
      pos 1041
      pos 1050
      pos 1708
      pos 2059
      pos 2422
      pos 2550
      pos 2586
      pos 2627
      pos 2982
      pos 3033
      pos 3122
      pos 3238
    doc 8
      freq 4
      pos 2199
      pos 2250
      pos 2339
      pos 2455
    doc 9
      freq 6
      pos 849
      pos 1134
      pos 1844
      pos 1895
      pos 1984
      pos 2100
    doc 10
      freq 27
      pos 2263
      pos 2465
      pos 2498
      pos 3136
      pos 3283
      pos 3765
      pos 4402
      pos 5287
      pos 5443
      pos 5476
      pos 6152
      pos 8081
      pos 8138
      pos 8197
      pos 8665
      pos 8831
      pos 9322
      pos 10982
      pos 11507
      pos 11607
      pos 11702
      pos 11803
      pos 11897
      pos 13505
      pos 13556
      pos 13645
      pos 13761
    doc 11
      freq 7
      pos 45
      pos 7193
      pos 7373
      pos 10666
      pos 10717
      pos 10806
      pos 10922
    doc 12
      freq 29
      pos 35
      pos 132
      pos 534
      pos 554
      pos 799
      pos 1141
      pos 2000
      pos 3006
      pos 3568
      pos 4074
      pos 4695
      pos 4815
      pos 4975
      pos 5210
      pos 5375
      pos 6599
      pos 6699
      pos 7448
      pos 7834
      pos 8019
      pos 8036
      pos 8586
      pos 8852
      pos 9007
      pos 9260
      pos 9516
      pos 9567
      pos 9656
      pos 9772
    doc 13
      freq 31
      pos 44
      pos 91
      pos 668
      pos 702
      pos 1574
      pos 1617
      pos 1625
      pos 1706
      pos 1749
      pos 3116
      pos 3538
      pos 4007
      pos 4234
      pos 4911
      pos 5660
      pos 5704
      pos 5718
      pos 5740
      pos 5759
      pos 5854
      pos 5894
      pos 6001
      pos 6034
      pos 6052
      pos 6134
      pos 6188
      pos 6230
      pos 7131
      pos 7182
      pos 7271
      pos 7387
    doc 14
      freq 6
      pos 294
      pos 2460
      pos 5597
      pos 5648
      pos 5737
      pos 5853
    doc 15
      freq 35
      pos 43
      pos 155
      pos 869
      pos 938
      pos 1036
      pos 1166
      pos 1175
      pos 1295
      pos 1465
      pos 1502
      pos 1515
      pos 1790
      pos 1818
      pos 1851
      pos 2289
      pos 2305
      pos 2339
      pos 2356
      pos 2725
      pos 2738
      pos 2755
      pos 2896
      pos 2924
      pos 3380
      pos 3425
      pos 3505
      pos 3538
      pos 3626
      pos 3645
      pos 3702
      pos 3716
      pos 4116
      pos 4167
      pos 4256
      pos 4372
    doc 16
      freq 4
      pos 2727
      pos 2778
      pos 2867
      pos 2983
    doc 17
      freq 9
      pos 942
      pos 1896
      pos 1914
      pos 2012
      pos 2130
      pos 2451
      pos 2502
      pos 2591
      pos 2707
    doc 18
      freq 5
      pos 548
      pos 2239
      pos 2290
      pos 2379
      pos 2495
    skipList 
      level 0
        skipDoc 7
        skipDocFP 1144296
        impacts 
          impact 
            freq 15
            norm 100
          impact 
            freq 17
            norm 113
          impact 
            freq 45
            norm 120
        impactsEnd 
        skipDoc 15
        skipDocFP 1146482
        impacts 
          impact 
            freq 6
            norm 95
          impact 
            freq 35
            norm 104
        impactsEnd 
  term informational
    doc 2
      freq 24
      pos 14
      pos 192
      pos 621
      pos 1071
      pos 1465
      pos 1840
      pos 2213
      pos 2450
      pos 2694
      pos 2943
      pos 3199
      pos 3440
      pos 3483
      pos 3866
      pos 4250
      pos 4658
      pos 4780
      pos 5019
      pos 5415
      pos 5820
      pos 6213
      pos 6327
      pos 6390
      pos 6721
    doc 4
      freq 10
      pos 209
      pos 693
      pos 725
      pos 803
      pos 829
      pos 997
      pos 1419
      pos 3540
      pos 4827
      pos 5169
    doc 6
      freq 11
      pos 12
      pos 284
      pos 737
      pos 1127
      pos 1608
      pos 2023
      pos 2337
      pos 2753
      pos 3030
      pos 3220
      pos 3559
    doc 7
      freq 12
      pos 13
      pos 197
      pos 584
      pos 948
      pos 1298
      pos 1646
      pos 1820
      pos 2174
      pos 2532
      pos 2887
      pos 2934
      pos 3264
    doc 11
      freq 56
      pos 13
      pos 76
      pos 186
      pos 489
      pos 563
      pos 816
      pos 1042
      pos 1249
      pos 1435
      pos 1569
      pos 1893
      pos 2107
      pos 2287
      pos 2539
      pos 2780
      pos 3048
      pos 3315
      pos 3438
      pos 3683
      pos 3879
      pos 3980
      pos 4166
      pos 4406
      pos 4649
      pos 4887
      pos 5065
      pos 5232
      pos 5389
      pos 5537
      pos 5697
      pos 5829
      pos 6017
      pos 6241
      pos 6477
      pos 6713
      pos 6927
      pos 7137
      pos 7265
      pos 7543
      pos 7777
      pos 8024
      pos 8221
      pos 8453
      pos 8637
      pos 8856
      pos 8955
      pos 9200
      pos 9410
      pos 9717
      pos 9855
      pos 10021
      pos 10211
      pos 10420
      pos 10513
      pos 10616
      pos 10949
    doc 12
      freq 30
      pos 11
      pos 234
      pos 496
      pos 860
      pos 1218
      pos 1555
      pos 1940
      pos 2274
      pos 2645
      pos 3017
      pos 3381
      pos 3810
      pos 4192
      pos 4557
      pos 5008
      pos 5417
      pos 5853
      pos 6243
      pos 6636
      pos 6981
      pos 7228
      pos 7457
      pos 7701
      pos 7881
      pos 8234
      pos 8631
      pos 9043
      pos 9415
      pos 9466
      pos 9799
    doc 13
      freq 24
      pos 12
      pos 119
      pos 349
      pos 753
      pos 1135
      pos 1456
      pos 1815
      pos 2167
      pos 2559
      pos 2930
      pos 3297
      pos 3658
      pos 3959
      pos 4294
      pos 4669
      pos 5014
      pos 5376
      pos 5726
      pos 6005
      pos 6327
      pos 6649
      pos 6939
      pos 7079
      pos 7414
    doc 15
      freq 15
      pos 13
      pos 189
      pos 300
      pos 630
      pos 1020
      pos 1388
      pos 1748
      pos 2143
      pos 2589
      pos 3001
      pos 3402
      pos 3797
      pos 4003
      pos 4066
      pos 4399
    skipList 
      level 0
        skipDoc 15
        skipDocFP 1149689
        impacts 
          impact 
            freq 12
            norm 100
          impact 
            freq 15
            norm 104
          impact 
            freq 24
            norm 108
          impact 
            freq 30
            norm 113
          impact 
            freq 56
            norm 114
        impactsEnd 
  term informativ
    doc 0
      freq 2
      pos 177
      pos 17129
    doc 1
      freq 2
      pos 404
      pos 8972
    doc 2
      freq 2
      pos 159
      pos 2225
    doc 3
      freq 2
      pos 280
      pos 4512
    doc 4
      freq 6
      pos 267
      pos 1240
      pos 2680
      pos 3450
      pos 5301
      pos 5874
    doc 5
      freq 2
      pos 342
      pos 4239
    doc 6
      freq 1
      pos 2867
    doc 8
      freq 2
      pos 176
      pos 1782
    doc 9
      freq 2
      pos 147
      pos 1735
    doc 10
      freq 3
      pos 387
      pos 1781
      pos 13284
    doc 11
      freq 2
      pos 539
      pos 9617
    doc 12
      freq 2
      pos 444
      pos 7469
    doc 13
      freq 2
      pos 340
      pos 6755
    doc 14
      freq 2
      pos 279
      pos 5466
    doc 15
      freq 2
      pos 294
      pos 3896
    doc 17
      freq 1
      pos 2120
    skipList 
      level 0
        skipDoc 8
        skipDocFP 1153002
        impacts 
          impact 
            freq 2
            norm 97
          impact 
            freq 6
            norm 108
        impactsEnd 
        skipDoc 17
        skipDocFP 1153465
        impacts 
          impact 
            freq 2
            norm 95
          impact 
            freq 3
            norm 116
        impactsEnd 
  term informs
    doc 1
      freq 1
      pos 798
  term infrastructur
    doc 6
      freq 1
      pos 1687
    doc 10
      freq 3
      pos 1672
      pos 13241
      pos 13264
    doc 12
      freq 1
      pos 2575
    doc 13
      freq 1
      pos 1801
    doc 17
      freq 1
      pos 2061
  term infrequently
    doc 13
      freq 1
      pos 2510
  term infring
    doc 0
      freq 1
      pos 17317
    doc 1
      freq 1
      pos 9698
    doc 2
      freq 1
      pos 6495
    doc 3
      freq 1
      pos 6047
    doc 4
      freq 1
      pos 6202
    doc 5
      freq 1
      pos 4532
    doc 6
      freq 1
      pos 3332
    doc 7
      freq 1
      pos 3037
    doc 8
      freq 1
      pos 2254
    doc 9
      freq 1
      pos 1899
    doc 10
      freq 1
      pos 13560
    doc 11
      freq 1
      pos 10721
    doc 12
      freq 1
      pos 9571
    doc 13
      freq 1
      pos 7186
    doc 14
      freq 1
      pos 5652
    doc 15
      freq 1
      pos 4171
    doc 16
      freq 1
      pos 2782
    doc 17
      freq 1
      pos 2506
    doc 18
      freq 1
      pos 2294
    skipList 
      level 0
        skipDoc 7
        skipDocFP 1154684
        impacts 
          impact 
            freq 1
            norm 100
        impactsEnd 
        skipDoc 15
        skipDocFP 1154989
        impacts 
          impact 
            freq 1
            norm 95
        impactsEnd 
  term ingram
    doc 11
      freq 1
      pos 9596
  term ingress
    doc 1
      freq 7
      pos 1124
      pos 1201
      pos 2674
      pos 3979
      pos 4369
      pos 4382
      pos 5990
    doc 3
      freq 10
      pos 780
      pos 1354
      pos 1959
      pos 2051
      pos 2091
      pos 3078
      pos 3580
      pos 3786
      pos 4263
      pos 5054
    doc 4
      freq 4
      pos 2195
      pos 2618
      pos 5111
      pos 5699
    doc 8
      freq 2
      pos 1601
      pos 1618
    doc 12
      freq 3
      pos 5544
      pos 6890
      pos 7533
  term inherently
    doc 10
      freq 1
      pos 1416
    doc 13
      freq 1
      pos 5472
  term inherited
    doc 2
      freq 1
      pos 5703
  term initial
    doc 0
      freq 2
      pos 1241
      pos 12398
    doc 1
      freq 4
      pos 5646
      pos 5763
      pos 5885
      pos 5950
    doc 2
      freq 3
      pos 2853
      pos 4247
      pos 4446
    doc 3
      freq 1
      pos 1991
    doc 4
      freq 1
      pos 3168
    doc 5
      freq 7
      pos 588
      pos 911
      pos 1457
      pos 1536
      pos 2708
      pos 3667
      pos 3875
    doc 6
      freq 1
      pos 1813
    doc 7
      freq 2
      pos 417
      pos 470
    doc 8
      freq 5
      pos 618
      pos 996
      pos 1290
      pos 1485
      pos 1573
    doc 10
      freq 1
      pos 1757
    skipList 
      level 0
        skipDoc 7
        skipDocFP 1156464
        impacts 
          impact 
            freq 2
            norm 100
          impact 
            freq 7
            norm 104
        impactsEnd 
  term initialization
    doc 0
      freq 4
      pos 6158
      pos 6646
      pos 7979
      pos 9348
  term initialized
    doc 0
      freq 1
      pos 6628
    doc 4
      freq 2
      pos 2215
      pos 3102
  term initializing
    doc 0
      freq 3
      pos 8971
      pos 9002
      pos 12646
  term initiat
    doc 1
      freq 1
      pos 4746
  term initiated
    doc 1
      freq 1
      pos 7351
    doc 10
      freq 1
      pos 6934
    doc 12
      freq 1
      pos 4672
  term initiates
    doc 1
      freq 2
      pos 2860
      pos 4371
  term initiation
    doc 5
      freq 2
      pos 2913
      pos 4335
    doc 10
      freq 9
      pos 27
      pos 98
      pos 419
      pos 13110
      pos 13144
      pos 13158
      pos 13172
      pos 13299
      pos 13393
    doc 11
      freq 4
      pos 32
      pos 82
      pos 587
      pos 9649
    doc 13
      freq 4
      pos 1165
      pos 1596
      pos 6848
      pos 6910
  term initiator
    doc 5
      freq 6
      pos 2292
      pos 2325
      pos 2366
      pos 2389
      pos 2495
      pos 2522
  term innumerabl
    doc 10
      freq 1
      pos 12145
  term input
    doc 1
      freq 1
      pos 7409
    doc 2
      freq 3
      pos 2369
      pos 3857
      pos 5786
    doc 3
      freq 5
      pos 1826
      pos 1873
      pos 2069
      pos 2786
      pos 3121
    doc 7
      freq 4
      pos 126
      pos 460
      pos 488
      pos 1831
    doc 10
      freq 3
      pos 3842
      pos 12360
      pos 12438
    doc 11
      freq 4
      pos 9335
      pos 9348
      pos 9777
      pos 9845
    doc 14
      freq 1
      pos 5356
    doc 15
      freq 1
      pos 3839
    doc 16
      freq 1
      pos 1588
    skipList 
      level 0
        skipDoc 15
        skipDocFP 1158475
        impacts 
          impact 
            freq 4
            norm 100
          impact 
            freq 5
            norm 107
        impactsEnd 
  term inquiry
    doc 13
      freq 1
      pos 6000
  term insecur
    doc 0
      freq 1
      pos 16045
    doc 12
      freq 1
      pos 4530
  term insecurity
    doc 10
      freq 1
      pos 10708
  term insert
    doc 1
      freq 1
      pos 8094
    doc 10
      freq 3
      pos 3000
      pos 8863
      pos 8916
    doc 12
      freq 1
      pos 5783
  term inserted
    doc 1
      freq 1
      pos 2007
    doc 10
      freq 2
      pos 1939
      pos 8967
    doc 12
      freq 2
      pos 5938
      pos 5962
    doc 16
      freq 1
      pos 1140
  term inserting
    doc 10
      freq 1
      pos 9024
    doc 12
      freq 1
      pos 6026
    doc 16
      freq 1
      pos 1147
  term insertion
    doc 1
      freq 2
      pos 8082
      pos 8106
    doc 13
      freq 1
      pos 2140
  term inserts
    doc 10
      freq 1
      pos 1999
  term insid
    doc 3
      freq 1
      pos 2063
    doc 11
      freq 2
      pos 1036
      pos 1122
    doc 12
      freq 1
      pos 2410
  term insler
    doc 8
      freq 1
      pos 2041
  term inspect
    doc 3
      freq 1
      pos 2660
    doc 10
      freq 2
      pos 3820
      pos 4686
  term inspecting
    doc 10
      freq 1
      pos 11107
  term inspection
    doc 1
      freq 2
      pos 8009
      pos 8229
  term install
    doc 12
      freq 1
      pos 4775
  term installed
    doc 6
      freq 1
      pos 483
  term instanc
    doc 0
      freq 6
      pos 471
      pos 538
      pos 3117
      pos 5273
      pos 5322
      pos 16850
    doc 1
      freq 2
      pos 4523
      pos 8793
    doc 2
      freq 1
      pos 797
    doc 6
      freq 1
      pos 252
    doc 7
      freq 2
      pos 1382
      pos 1413
    doc 10
      freq 2
      pos 2912
      pos 8724
    doc 13
      freq 5
      pos 2389
      pos 2785
      pos 4115
      pos 5436
      pos 5579
    doc 15
      freq 2
      pos 1864
      pos 1873
    skipList 
      level 0
        skipDoc 15
        skipDocFP 1160675
        impacts 
          impact 
            freq 2
            norm 100
          impact 
            freq 5
            norm 109
          impact 
            freq 6
            norm 120
        impactsEnd 
  term instances
    doc 0
      freq 3
      pos 3641
      pos 4157
      pos 10999
  term instantaneous
    doc 6
      freq 2
      pos 545
      pos 1279
  term instantiat
    doc 10
      freq 3
      pos 1768
      pos 2145
      pos 4576
  term instantiated
    doc 10
      freq 6
      pos 2117
      pos 2169
      pos 2216
      pos 2577
      pos 2674
      pos 9145
    doc 13
      freq 1
      pos 5585
    doc 18
      freq 11
      pos 194
      pos 559
      pos 582
      pos 633
      pos 642
      pos 662
      pos 980
      pos 1606
      pos 1622
      pos 1830
      pos 1855
  term instantiates
    doc 10
      freq 3
      pos 2129
      pos 6316
      pos 6955
  term instantiating
    doc 10
      freq 1
      pos 2319
  term instead
    doc 0
      freq 2
      pos 3580
      pos 16809
    doc 2
      freq 1
      pos 1579
    doc 5
      freq 1
      pos 3264
    doc 6
      freq 1
      pos 790
    doc 11
      freq 2
      pos 691
      pos 1699
    doc 12
      freq 16
      pos 258
      pos 1710
      pos 1739
      pos 1796
      pos 1991
      pos 2119
      pos 2159
      pos 2587
      pos 3641
      pos 4320
      pos 4454
      pos 6024
      pos 6168
      pos 8355
      pos 8657
      pos 9023
    doc 15
      freq 1
      pos 2551
    doc 16
      freq 1
      pos 235
    doc 18
      freq 1
      pos 1247
    skipList 
      level 0
        skipDoc 16
        skipDocFP 1162224
        impacts 
          impact 
            freq 1
            norm 99
          impact 
            freq 16
            norm 113
        impactsEnd 
  term institut
    doc 1
      freq 1
      pos 9125
    doc 2
      freq 1
      pos 2392
  term instructions
    doc 8
      freq 1
      pos 98
  term insuf
    doc 11
      freq 1
      pos 7206
  term int
    doc 10
      freq 1
      pos 10306
  term intact
    doc 10
      freq 2
      pos 8913
      pos 12350
    doc 11
      freq 1
      pos 9767
  term integer
    doc 0
      freq 34
      pos 1596
      pos 1622
      pos 1646
      pos 1693
      pos 1709
      pos 1847
      pos 1876
      pos 1902
      pos 1942
      pos 2002
      pos 2286
      pos 5490
      pos 5498
      pos 5721
      pos 5937
      pos 7803
      pos 7838
      pos 8347
      pos 8390
      pos 8889
      pos 8891
      pos 8895
      pos 8968
      pos 8999
      pos 9089
      pos 10055
      pos 10067
      pos 10234
      pos 10798
      pos 11053
      pos 11067
      pos 11348
      pos 11652
      pos 12631
    doc 5
      freq 6
      pos 1268
      pos 1310
      pos 1363
      pos 1436
      pos 2010
      pos 2020
    doc 8
      freq 3
      pos 953
      pos 1264
      pos 1459
    doc 11
      freq 1
      pos 1340
  term integers
    doc 8
      freq 1
      pos 959
  term integral
    doc 4
      freq 1
      pos 504
    doc 11
      freq 1
      pos 4625
  term integrated
    doc 0
      freq 5
      pos 381
      pos 1667
      pos 5449
      pos 6318
      pos 7789
    doc 6
      freq 1
      pos 2974
    doc 12
      freq 1
      pos 6152
  term integration
    doc 15
      freq 1
      pos 2323
  term integrity
    doc 1
      freq 2
      pos 8341
      pos 8652
    doc 3
      freq 2
      pos 1451
      pos 1468
    doc 5
      freq 7
      pos 405
      pos 713
      pos 899
      pos 3020
      pos 3139
      pos 3227
      pos 3375
    doc 10
      freq 12
      pos 4348
      pos 4366
      pos 8024
      pos 8262
      pos 8479
      pos 9219
      pos 10135
      pos 10187
      pos 10220
      pos 10224
      pos 10309
      pos 13008
    doc 13
      freq 7
      pos 313
      pos 5788
      pos 5865
      pos 5879
      pos 5931
      pos 5988
      pos 6630
  term intellectual
    doc 0
      freq 2
      pos 17332
      pos 17346
    doc 1
      freq 2
      pos 9713
      pos 9727
    doc 2
      freq 2
      pos 6510
      pos 6524
    doc 3
      freq 2
      pos 6062
      pos 6076
    doc 4
      freq 2
      pos 6217
      pos 6231
    doc 5
      freq 2
      pos 4547
      pos 4561
    doc 6
      freq 2
      pos 3347
      pos 3361
    doc 7
      freq 2
      pos 3052
      pos 3066
    doc 8
      freq 2
      pos 2269
      pos 2283
    doc 9
      freq 2
      pos 1914
      pos 1928
    doc 10
      freq 2
      pos 13575
      pos 13589
    doc 11
      freq 2
      pos 10736
      pos 10750
    doc 12
      freq 2
      pos 9586
      pos 9600
    doc 13
      freq 2
      pos 7201
      pos 7215
    doc 14
      freq 2
      pos 5667
      pos 5681
    doc 15
      freq 2
      pos 4186
      pos 4200
    doc 16
      freq 2
      pos 2797
      pos 2811
    doc 17
      freq 2
      pos 2521
      pos 2535
    doc 18
      freq 2
      pos 2309
      pos 2323
    skipList 
      level 0
        skipDoc 7
        skipDocFP 1165188
        impacts 
          impact 
            freq 2
            norm 100
        impactsEnd 
        skipDoc 15
        skipDocFP 1165614
        impacts 
          impact 
            freq 2
            norm 95
        impactsEnd 
  term intelligent
    doc 10
      freq 1
      pos 9985
    doc 15
      freq 1
      pos 2949
  term intelligently
    doc 10
      freq 1
      pos 4526
    doc 12
      freq 1
      pos 8977
  term intend
    doc 10
      freq 1
      pos 7625
  term intended
    doc 0
      freq 1
      pos 9039
    doc 1
      freq 1
      pos 2653
    doc 4
      freq 4
      pos 846
      pos 1029
      pos 4138
      pos 4186
    doc 5
      freq 1
      pos 633
    doc 6
      freq 4
      pos 201
      pos 278
      pos 791
      pos 857
    doc 9
      freq 2
      pos 1059
      pos 1136
    doc 10
      freq 5
      pos 3246
      pos 9281
      pos 9297
      pos 10168
      pos 10176
    doc 11
      freq 1
      pos 3933
    doc 13
      freq 6
      pos 1618
      pos 1915
      pos 1965
      pos 2765
      pos 4661
      pos 5405
    doc 17
      freq 1
      pos 1064
    skipList 
      level 0
        skipDoc 11
        skipDocFP 1166781
        impacts 
          impact 
            freq 2
            norm 95
          impact 
            freq 4
            norm 101
          impact 
            freq 5
            norm 116
        impactsEnd 
  term intent
    doc 6
      freq 1
      pos 716
    doc 7
      freq 2
      pos 418
      pos 1510
  term intention
    doc 4
      freq 1
      pos 4208
  term intentionally
    doc 13
      freq 1
      pos 1241
  term inter
    doc 2
      freq 5
      pos 2411
      pos 4326
      pos 5595
      pos 6052
      pos 6062
    doc 3
      freq 1
      pos 545
    doc 7
      freq 7
      pos 897
      pos 903
      pos 1418
      pos 2361
      pos 2367
      pos 2444
      pos 2461
  term interact
    doc 7
      freq 2
      pos 1127
      pos 2786
    doc 13
      freq 1
      pos 4771
  term interaction
    doc 6
      freq 1
      pos 138
    doc 13
      freq 2
      pos 3206
      pos 4314
  term interactions
    doc 5
      freq 1
      pos 2848
    doc 9
      freq 1
      pos 609
    doc 12
      freq 1
      pos 7934
    doc 13
      freq 1
      pos 1505
    doc 15
      freq 1
      pos 138
  term interactiv
    doc 3
      freq 2
      pos 5743
      pos 5754
    doc 12
      freq 1
      pos 2756
    doc 13
      freq 1
      pos 3167
  term interactively
    doc 13
      freq 2
      pos 774
      pos 5691
  term interacts
    doc 13
      freq 1
      pos 6322
  term intercept
    doc 10
      freq 1
      pos 8734
  term interconnect
    doc 7
      freq 2
      pos 859
      pos 2269
  term interconnection
    doc 0
      freq 1
      pos 16925
    doc 17
      freq 1
      pos 2016
  term interconnections
    doc 17
      freq 1
      pos 2134
  term interdomain
    doc 10
      freq 2
      pos 119
      pos 1548
  term interest
    doc 2
      freq 5
      pos 1055
      pos 1106
      pos 1110
      pos 4641
      pos 4808
    doc 6
      freq 1
      pos 2410
    doc 13
      freq 4
      pos 477
      pos 2215
      pos 3288
      pos 3813
    doc 15
      freq 1
      pos 2320
  term interested
    doc 0
      freq 1
      pos 17486
    doc 1
      freq 1
      pos 9867
    doc 2
      freq 2
      pos 3731
      pos 6664
    doc 3
      freq 1
      pos 6216
    doc 4
      freq 1
      pos 6371
    doc 5
      freq 1
      pos 4701
    doc 6
      freq 1
      pos 3501
    doc 7
      freq 1
      pos 3206
    doc 8
      freq 1
      pos 2423
    doc 9
      freq 1
      pos 2068
    doc 10
      freq 1
      pos 13729
    doc 11
      freq 1
      pos 10890
    doc 12
      freq 1
      pos 9740
    doc 13
      freq 5
      pos 2191
      pos 3512
      pos 4521
      pos 4902
      pos 7355
    doc 14
      freq 2
      pos 425
      pos 5821
    doc 15
      freq 1
      pos 4340
    doc 16
      freq 1
      pos 2951
    doc 17
      freq 1
      pos 2675
    doc 18
      freq 1
      pos 2463
    skipList 
      level 0
        skipDoc 7
        skipDocFP 1169540
        impacts 
          impact 
            freq 1
            norm 100
          impact 
            freq 2
            norm 108
        impactsEnd 
        skipDoc 15
        skipDocFP 1169860
        impacts 
          impact 
            freq 1
            norm 95
          impact 
            freq 2
            norm 107
          impact 
            freq 5
            norm 109
        impactsEnd 
  term interesting
    doc 11
      freq 3
      pos 1908
      pos 1987
      pos 2025
  term interfac
    doc 0
      freq 10
      pos 636
      pos 654
      pos 5372
      pos 5403
      pos 5606
      pos 5761
      pos 5916
      pos 7002
      pos 16056
      pos 16345
    doc 1
      freq 44
      pos 274
      pos 312
      pos 1598
      pos 1630
      pos 1656
      pos 2301
      pos 2498
      pos 2590
      pos 2622
      pos 2763
      pos 2775
      pos 2787
      pos 2806
      pos 2817
      pos 3024
      pos 3042
      pos 3861
      pos 3945
      pos 3962
      pos 4065
      pos 4588
      pos 5349
      pos 5521
      pos 5561
      pos 5656
      pos 5737
      pos 5967
      pos 5974
      pos 6077
      pos 6106
      pos 6119
      pos 6125
      pos 6135
      pos 6162
      pos 6214
      pos 6224
      pos 6238
      pos 6254
      pos 7176
      pos 7236
      pos 7311
      pos 7786
      pos 8179
      pos 9140
    doc 2
      freq 4
      pos 2718
      pos 3221
      pos 3257
      pos 3999
    doc 3
      freq 9
      pos 212
      pos 640
      pos 1930
      pos 1943
      pos 1979
      pos 1994
      pos 2007
      pos 2696
      pos 2901
    doc 4
      freq 4
      pos 2708
      pos 3687
      pos 3853
      pos 3932
    doc 8
      freq 6
      pos 131
      pos 806
      pos 820
      pos 998
      pos 1014
      pos 1033
    doc 10
      freq 4
      pos 4634
      pos 9565
      pos 9980
      pos 9986
    doc 12
      freq 7
      pos 1342
      pos 2550
      pos 2561
      pos 2564
      pos 3891
      pos 5748
      pos 5886
    doc 15
      freq 6
      pos 1228
      pos 1233
      pos 1246
      pos 1444
      pos 3489
      pos 3731
    skipList 
      level 0
        skipDoc 12
        skipDocFP 1170947
        impacts 
          impact 
            freq 6
            norm 97
          impact 
            freq 9
            norm 107
          impact 
            freq 44
            norm 113
        impactsEnd 
  term interfaceindex
    doc 0
      freq 3
      pos 1056
      pos 5484
      pos 5580
  term interfaces
    doc 0
      freq 2
      pos 16562
      pos 16987
    doc 1
      freq 2
      pos 8144
      pos 8146
    doc 2
      freq 3
      pos 261
      pos 270
      pos 3974
    doc 3
      freq 1
      pos 660
    doc 10
      freq 1
      pos 9598
    doc 13
      freq 1
      pos 2272
    doc 15
      freq 6
      pos 227
      pos 1204
      pos 1210
      pos 1218
      pos 1276
      pos 2447
  term interfer
    doc 10
      freq 1
      pos 9291
  term interim
    doc 2
      freq 1
      pos 5448
  term interior
    doc 6
      freq 1
      pos 2662
  term interleaving
    doc 13
      freq 2
      pos 2155
      pos 2344
  term intermediaries
    doc 10
      freq 8
      pos 1437
      pos 1461
      pos 1501
      pos 1766
      pos 2143
      pos 3407
      pos 8118
      pos 9019
    doc 13
      freq 3
      pos 5674
      pos 6125
      pos 6359
  term intermediary
    doc 10
      freq 5
      pos 2581
      pos 8956
      pos 9148
      pos 10039
      pos 10151
  term intermediat
    doc 0
      freq 72
      pos 21
      pos 24
      pos 118
      pos 121
      pos 310
      pos 313
      pos 514
      pos 582
      pos 771
      pos 789
      pos 808
      pos 1379
      pos 1442
      pos 1460
      pos 2346
      pos 2365
      pos 2398
      pos 2508
      pos 2562
      pos 2737
      pos 2754
      pos 2968
      pos 3054
      pos 3263
      pos 3293
      pos 3346
      pos 3383
      pos 3389
      pos 3433
      pos 3505
      pos 3546
      pos 3564
      pos 4445
      pos 4493
      pos 4539
      pos 4575
      pos 4774
      pos 4795
      pos 4851
      pos 5073
      pos 5425
      pos 6484
      pos 6521
      pos 6577
      pos 6598
      pos 6603
      pos 6735
      pos 6756
      pos 6958
      pos 7218
      pos 7404
      pos 7437
      pos 7765
      pos 8841
      pos 8865
      pos 9135
      pos 9303
      pos 9309
      pos 9387
      pos 9418
      pos 9466
      pos 9573
      pos 9617
      pos 9649
      pos 9810
      pos 9842
      pos 9873
      pos 13390
      pos 16888
      pos 16891
      pos 17157
      pos 17160
    doc 6
      freq 2
      pos 2263
      pos 2270
  term intermittent
    doc 0
      freq 2
      pos 16227
      pos 16380
    doc 13
      freq 7
      pos 271
      pos 2474
      pos 2658
      pos 4065
      pos 4077
      pos 4093
      pos 4172
  term intermittently
    doc 13
      freq 1
      pos 3816
  term internal
    doc 0
      freq 6
      pos 1835
      pos 1848
      pos 10519
      pos 10533
      pos 11545
      pos 11555
    doc 12
      freq 1
      pos 7970
    doc 16
      freq 3
      pos 663
      pos 1962
      pos 2330
  term international
    doc 6
      freq 1
      pos 3122
  term internationalizabl
    doc 10
      freq 1
      pos 9912
  term internet
    doc 0
      freq 14
      pos 36
      pos 42
      pos 59
      pos 85
      pos 108
      pos 143
      pos 194
      pos 209
      pos 1212
      pos 17121
      pos 17187
      pos 17229
      pos 17287
      pos 17291
    doc 1
      freq 7
      pos 53
      pos 59
      pos 76
      pos 102
      pos 9610
      pos 9668
      pos 9672
    doc 2
      freq 14
      pos 10
      pos 32
      pos 39
      pos 55
      pos 349
      pos 355
      pos 422
      pos 1505
      pos 2231
      pos 4764
      pos 5882
      pos 6407
      pos 6465
      pos 6469
    doc 3
      freq 7
      pos 47
      pos 53
      pos 70
      pos 96
      pos 5959
      pos 6017
      pos 6021
    doc 4
      freq 26
      pos 28
      pos 35
      pos 49
      pos 55
      pos 72
      pos 98
      pos 116
      pos 123
      pos 128
      pos 283
      pos 290
      pos 493
      pos 1473
      pos 4665
      pos 5182
      pos 5216
      pos 5233
      pos 5240
      pos 5256
      pos 5317
      pos 5376
      pos 5432
      pos 5887
      pos 6114
      pos 6172
      pos 6176
    doc 5
      freq 11
      pos 33
      pos 39
      pos 56
      pos 82
      pos 200
      pos 593
      pos 2817
      pos 4176
      pos 4444
      pos 4502
      pos 4506
    doc 6
      freq 9
      pos 35
      pos 42
      pos 58
      pos 73
      pos 878
      pos 2978
      pos 3239
      pos 3302
      pos 3306
    doc 7
      freq 21
      pos 46
      pos 53
      pos 69
      pos 713
      pos 736
      pos 799
      pos 814
      pos 828
      pos 842
      pos 1807
      pos 2023
      pos 2037
      pos 2073
      pos 2093
      pos 2209
      pos 2224
      pos 2238
      pos 2252
      pos 2949
      pos 3007
      pos 3011
    doc 8
      freq 6
      pos 37
      pos 43
      pos 63
      pos 2166
      pos 2224
      pos 2228
    doc 9
      freq 8
      pos 35
      pos 41
      pos 58
      pos 84
      pos 631
      pos 1811
      pos 1869
      pos 1873
    doc 10
      freq 11
      pos 38
      pos 44
      pos 61
      pos 87
      pos 747
      pos 1528
      pos 13236
      pos 13259
      pos 13472
      pos 13530
      pos 13534
    doc 11
      freq 9
      pos 48
      pos 55
      pos 71
      pos 747
      pos 9344
      pos 9622
      pos 10633
      pos 10691
      pos 10695
    doc 12
      freq 12
      pos 38
      pos 45
      pos 61
      pos 1485
      pos 2627
      pos 5489
      pos 7209
      pos 7250
      pos 7512
      pos 9483
      pos 9541
      pos 9545
    doc 13
      freq 50
      pos 33
      pos 47
      pos 54
      pos 70
      pos 87
      pos 126
      pos 185
      pos 193
      pos 356
      pos 397
      pos 570
      pos 591
      pos 760
      pos 856
      pos 882
      pos 1033
      pos 1142
      pos 1215
      pos 1463
      pos 1551
      pos 1822
      pos 2030
      pos 2174
      pos 2432
      pos 2566
      pos 2577
      pos 2659
      pos 2937
      pos 3304
      pos 3665
      pos 3966
      pos 4159
      pos 4168
      pos 4202
      pos 4214
      pos 4301
      pos 4676
      pos 5021
      pos 5383
      pos 5653
      pos 5733
      pos 6012
      pos 6334
      pos 6656
      pos 6872
      pos 6946
      pos 7086
      pos 7098
      pos 7156
      pos 7160
    doc 14
      freq 6
      pos 35
      pos 42
      pos 65
      pos 5564
      pos 5622
      pos 5626
    doc 15
      freq 6
      pos 46
      pos 53
      pos 69
      pos 4083
      pos 4141
      pos 4145
    doc 16
      freq 18
      pos 19
      pos 34
      pos 40
      pos 57
      pos 83
      pos 92
      pos 181
      pos 1075
      pos 1083
      pos 2525
      pos 2548
      pos 2562
      pos 2576
      pos 2584
      pos 2594
      pos 2694
      pos 2752
      pos 2756
    doc 17
      freq 17
      pos 31
      pos 37
      pos 54
      pos 80
      pos 533
      pos 832
      pos 870
      pos 895
      pos 2056
      pos 2080
      pos 2177
      pos 2217
      pos 2242
      pos 2259
      pos 2418
      pos 2476
      pos 2480
    doc 18
      freq 8
      pos 40
      pos 46
      pos 63
      pos 89
      pos 1674
      pos 2206
      pos 2264
      pos 2268
    skipList 
      level 0
        skipDoc 7
        skipDocFP 1175759
        impacts 
          impact 
            freq 21
            norm 100
          impact 
            freq 26
            norm 108
        impactsEnd 
        skipDoc 15
        skipDocFP 1177501
        impacts 
          impact 
            freq 8
            norm 95
          impact 
            freq 50
            norm 109
        impactsEnd 
  term internets
    doc 0
      freq 2
      pos 1085
      pos 1094
  term internetworking
    doc 7
      freq 2
      pos 997
      pos 2485
  term interoperability
    doc 2
      freq 2
      pos 1598
      pos 2408
    doc 3
      freq 2
      pos 289
      pos 5012
    doc 11
      freq 3
      pos 617
      pos 701
      pos 4190
    doc 17
      freq 1
      pos 936
  term interoperabl
    doc 13
      freq 2
      pos 3688
      pos 5137
  term interoperat
    doc 1
      freq 2
      pos 3994
      pos 6005
    doc 3
      freq 1
      pos 1974
  term interpret
    doc 11
      freq 2
      pos 2152
      pos 6114
    doc 13
      freq 1
      pos 5166
  term interpretation
    doc 0
      freq 1
      pos 5805
    doc 1
      freq 2
      pos 3549
      pos 3867
  term interpreted
    doc 0
      freq 1
      pos 979
    doc 1
      freq 1
      pos 1181
    doc 2
      freq 1
      pos 5079
    doc 3
      freq 1
      pos 1256
    doc 4
      freq 1
      pos 465
    doc 5
      freq 1
      pos 1069
    doc 8
      freq 1
      pos 329
    doc 9
      freq 1
      pos 366
    doc 10
      freq 1
      pos 696
    doc 11
      freq 1
      pos 8667
    doc 13
      freq 1
      pos 1205
    doc 16
      freq 1
      pos 841
    doc 17
      freq 1
      pos 289
    doc 18
      freq 1
      pos 404
    skipList 
      level 0
        skipDoc 9
        skipDocFP 1181169
        impacts 
          impact 
            freq 1
            norm 95
        impactsEnd 
  term interprets
    doc 1
      freq 1
      pos 4423
  term interval
    doc 0
      freq 11
      pos 2115
      pos 2160
      pos 2179
      pos 2191
      pos 2554
      pos 4834
      pos 6991
      pos 7031
      pos 7108
      pos 7166
      pos 16504
    doc 1
      freq 1
      pos 7515
    doc 5
      freq 4
      pos 1392
      pos 1950
      pos 2029
      pos 3325
    doc 6
      freq 17
      pos 1326
      pos 1409
      pos 1413
      pos 1448
      pos 1718
      pos 1774
      pos 1827
      pos 1830
      pos 1873
      pos 1912
      pos 1929
      pos 1943
      pos 1950
      pos 1997
      pos 2020
      pos 2059
      pos 2300
    doc 10
      freq 4
      pos 8508
      pos 8556
      pos 8607
      pos 8630
  term intervals
    doc 5
      freq 2
      pos 1412
      pos 1968
    doc 6
      freq 4
      pos 1047
      pos 1528
      pos 1991
      pos 2372
  term intervening
    doc 1
      freq 1
      pos 1210
  term interworking
    doc 3
      freq 2
      pos 252
      pos 3146
  term interwoven
    doc 15
      freq 1
      pos 3737
  term intf
    doc 1
      freq 1
      pos 4037
  term intmeth
    doc 11
      freq 1
      pos 1906
  term intmeth.word
    doc 11
      freq 1
      pos 1982
  term into
    doc 0
      freq 6
      pos 722
      pos 2788
      pos 3515
      pos 4071
      pos 4120
      pos 7890
    doc 1
      freq 5
      pos 2877
      pos 3569
      pos 7600
      pos 8098
      pos 8269
    doc 2
      freq 6
      pos 404
      pos 961
      pos 1119
      pos 3755
      pos 3917
      pos 6261
    doc 4
      freq 3
      pos 687
      pos 2478
      pos 5871
    doc 7
      freq 1
      pos 1553
    doc 8
      freq 1
      pos 230
    doc 9
      freq 2
      pos 879
      pos 1473
    doc 10
      freq 5
      pos 7643
      pos 8433
      pos 8679
      pos 8749
      pos 9535
    doc 11
      freq 5
      pos 625
      pos 872
      pos 4623
      pos 5917
      pos 6562
    doc 12
      freq 3
      pos 1096
      pos 2786
      pos 4316
    doc 13
      freq 1
      pos 2147
    doc 15
      freq 1
      pos 2953
    doc 16
      freq 2
      pos 278
      pos 1136
    doc 18
      freq 2
      pos 1564
      pos 1609
    skipList 
      level 0
        skipDoc 10
        skipDocFP 1183125
        impacts 
          impact 
            freq 2
            norm 95
          impact 
            freq 6
            norm 108
        impactsEnd 
  term intpernet
    doc 4
      freq 1
      pos 5335
  term intra
    doc 0
      freq 1
      pos 5807
  term intradomain
    doc 10
      freq 1
      pos 1550
  term introduc
    doc 2
      freq 1
      pos 2177
    doc 4
      freq 1
      pos 365
    doc 6
      freq 1
      pos 965
    doc 11
      freq 1
      pos 5447
    doc 12
      freq 1
      pos 3516
    doc 13
      freq 1
      pos 5102
    doc 15
      freq 1
      pos 1667
  term introduced
    doc 0
      freq 1
      pos 15859
    doc 2
      freq 1
      pos 4814
    doc 6
      freq 1
      pos 388
    doc 14
      freq 1
      pos 1235
    doc 15
      freq 1
      pos 2502
  term introduces
    doc 5
      freq 1
      pos 2679
    doc 9
      freq 1
      pos 154
    doc 10
      freq 2
      pos 3796
      pos 5644
    doc 12
      freq 1
      pos 712
    doc 14
      freq 2
      pos 2730
      pos 2813
    doc 15
      freq 1
      pos 3150
  term introduction
    doc 0
      freq 1
      pos 17182
    doc 1
      freq 2
      pos 215
      pos 435
    doc 2
      freq 2
      pos 116
      pos 204
    doc 3
      freq 2
      pos 180
      pos 342
    doc 4
      freq 2
      pos 152
      pos 281
    doc 5
      freq 3
      pos 258
      pos 358
      pos 4205
    doc 6
      freq 1
      pos 298
    doc 7
      freq 3
      pos 116
      pos 156
      pos 1433
    doc 8
      freq 2
      pos 109
      pos 194
    doc 9
      freq 3
      pos 118
      pos 151
      pos 1643
    doc 10
      freq 2
      pos 182
      pos 403
    doc 12
      freq 2
      pos 149
      pos 508
    doc 13
      freq 2
      pos 136
      pos 363
    doc 14
      freq 2
      pos 122
      pos 283
    doc 15
      freq 2
      pos 204
      pos 312
    doc 16
      freq 1
      pos 175
    doc 17
      freq 1
      pos 163
    doc 18
      freq 3
      pos 153
      pos 184
      pos 2073
    skipList 
      level 0
        skipDoc 7
        skipDocFP 1185271
        impacts 
          impact 
            freq 3
            norm 100
        impactsEnd 
        skipDoc 16
        skipDocFP 1185683
        impacts 
          impact 
            freq 3
            norm 95
        impactsEnd 
  term intruder
    doc 0
      freq 2
      pos 16434
      pos 16679
  term inv
    doc 10
      freq 2
      pos 5790
      pos 5820
  term inv2543
    doc 11
      freq 1
      pos 9243
  term inv2543.1717
    doc 11
      freq 1
      pos 9276
  term invalid
    doc 10
      freq 6
      pos 339
      pos 4237
      pos 8614
      pos 8637
      pos 11845
      pos 11923
    doc 11
      freq 16
      pos 245
      pos 329
      pos 661
      pos 676
      pos 1295
      pos 1394
      pos 4116
      pos 4178
      pos 4184
      pos 4218
      pos 4254
      pos 5251
      pos 6029
      pos 6039
      pos 6149
      pos 8258
    doc 16
      freq 4
      pos 627
      pos 1278
      pos 1282
      pos 2283
  term invalidat
    doc 13
      freq 2
      pos 4222
      pos 4258
  term invalidating
    doc 13
      freq 1
      pos 5918
  term invers
    doc 2
      freq 3
      pos 2977
      pos 6122
      pos 6143
  term investigated
    doc 12
      freq 1
      pos 1892
  term investigating
    doc 13
      freq 2
      pos 1151
      pos 1569
  term invit
    doc 10
      freq 12
      pos 1122
      pos 1822
      pos 1839
      pos 6296
      pos 6305
      pos 6321
      pos 6349
      pos 6411
      pos 6486
      pos 6606
      pos 6634
      pos 8667
    doc 11
      freq 60
      pos 140
      pos 525
      pos 1203
      pos 1449
      pos 1481
      pos 1645
      pos 2010
      pos 2194
      pos 2221
      pos 2794
      pos 2886
      pos 3251
      pos 3289
      pos 3303
      pos 3363
      pos 3386
      pos 4022
      pos 4145
      pos 4271
      pos 4292
      pos 4447
      pos 4472
      pos 4663
      pos 4685
      pos 5151
      pos 5179
      pos 5248
      pos 5312
      pos 5335
      pos 5408
      pos 5452
      pos 5480
      pos 5556
      pos 5618
      pos 5640
      pos 5848
      pos 5928
      pos 5962
      pos 6037
      pos 6153
      pos 6176
      pos 6785
      pos 6877
      pos 6983
      pos 7207
      pos 7214
      pos 7793
      pos 7827
      pos 7846
      pos 7872
      pos 8122
      pos 8143
      pos 8150
      pos 8491
      pos 9054
      pos 9064
      pos 9093
      pos 9146
      pos 9244
      pos 9280
  term invitations
    doc 13
      freq 1
      pos 1911
  term invites
    doc 0
      freq 1
      pos 17484
    doc 1
      freq 1
      pos 9865
    doc 2
      freq 1
      pos 6662
    doc 3
      freq 1
      pos 6214
    doc 4
      freq 1
      pos 6369
    doc 5
      freq 1
      pos 4699
    doc 6
      freq 1
      pos 3499
    doc 7
      freq 1
      pos 3204
    doc 8
      freq 1
      pos 2421
    doc 9
      freq 1
      pos 2066
    doc 10
      freq 1
      pos 13727
    doc 11
      freq 1
      pos 10888
    doc 12
      freq 1
      pos 9738
    doc 13
      freq 1
      pos 7353
    doc 14
      freq 1
      pos 5819
    doc 15
      freq 1
      pos 4338
    doc 16
      freq 1
      pos 2949
    doc 17
      freq 1
      pos 2673
    doc 18
      freq 1
      pos 2461
    skipList 
      level 0
        skipDoc 7
        skipDocFP 1188792
        impacts 
          impact 
            freq 1
            norm 100
        impactsEnd 
        skipDoc 15
        skipDocFP 1189097
        impacts 
          impact 
            freq 1
            norm 95
        impactsEnd 
  term invoking
    doc 4
      freq 16
      pos 1026
      pos 1446
      pos 2135
      pos 2161
      pos 2801
      pos 2827
      pos 3046
      pos 3072
      pos 3282
      pos 3308
      pos 3338
      pos 3772
      pos 3787
      pos 3813
      pos 3822
      pos 5630
  term involv
    doc 13
      freq 1
      pos 3794
  term involved
    doc 2
      freq 6
      pos 1207
      pos 1948
      pos 4353
      pos 4846
      pos 5517
      pos 5964
    doc 5
      freq 2
      pos 744
      pos 1425
    doc 17
      freq 1
      pos 1829
  term involvement
    doc 2
      freq 1
      pos 4500
  term involves
    doc 13
      freq 1
      pos 1496
    doc 14
      freq 2
      pos 316
      pos 5316
    doc 18
      freq 1
      pos 576
  term involving
    doc 6
      freq 1
      pos 354
  term invut
    doc 11
      freq 2
      pos 7845
      pos 7868
  term iohs2
    doc 11
      freq 1
      pos 10327
  term ip
    doc 0
      freq 50
      pos 136
      pos 334
      pos 377
      pos 785
      pos 857
      pos 867
      pos 1084
      pos 1093
      pos 1149
      pos 1188
      pos 1356
      pos 1675
      pos 1698
      pos 1808
      pos 3534
      pos 3559
      pos 3603
      pos 3707
      pos 3728
      pos 3785
      pos 4112
      pos 4219
      pos 4240
      pos 4297
      pos 9556
      pos 9562
      pos 9569
      pos 9613
      pos 9643
      pos 9700
      pos 9725
      pos 9763
      pos 10859
      pos 10869
      pos 10899
      pos 10933
      pos 10943
      pos 11084
      pos 11117
      pos 11162
      pos 11291
      pos 11322
      pos 11364
      pos 11416
      pos 11468
      pos 11623
      pos 15759
      pos 15883
      pos 16003
      pos 16972
    doc 1
      freq 9
      pos 236
      pos 1982
      pos 1989
      pos 2015
      pos 2021
      pos 3196
      pos 8487
      pos 8515
      pos 9090
    doc 2
      freq 1
      pos 6096
    doc 3
      freq 1
      pos 3379
    doc 4
      freq 10
      pos 4038
      pos 4044
      pos 4063
      pos 4115
      pos 4249
      pos 4369
      pos 5204
      pos 5358
      pos 5386
      pos 5412
    doc 6
      freq 10
      pos 213
      pos 866
      pos 1024
      pos 2081
      pos 2099
      pos 2107
      pos 2916
      pos 3001
      pos 3014
      pos 3020
    doc 7
      freq 13
      pos 692
      pos 865
      pos 1097
      pos 1961
      pos 1979
      pos 1988
      pos 2275
      pos 2327
      pos 2453
      pos 2657
      pos 2667
      pos 2713
      pos 2719
    doc 8
      freq 2
      pos 692
      pos 2048
    doc 9
      freq 1
      pos 1750
    doc 10
      freq 1
      pos 7405
    doc 12
      freq 18
      pos 905
      pos 1050
      pos 4450
      pos 4523
      pos 4753
      pos 5069
      pos 5090
      pos 5163
      pos 5509
      pos 5722
      pos 5826
      pos 5836
      pos 6418
      pos 6466
      pos 6583
      pos 7273
      pos 7429
      pos 9236
    doc 13
      freq 10
      pos 173
      pos 520
      pos 540
      pos 552
      pos 2012
      pos 2018
      pos 2024
      pos 2111
      pos 2232
      pos 6926
    doc 15
      freq 5
      pos 135
      pos 659
      pos 1537
      pos 2090
      pos 3361
    skipList 
      level 0
        skipDoc 8
        skipDocFP 1190772
        impacts 
          impact 
            freq 2
            norm 97
          impact 
            freq 13
            norm 100
          impact 
            freq 50
            norm 120
        impactsEnd 
  term ip4
    doc 10
      freq 6
      pos 6380
      pos 6388
      pos 6505
      pos 6513
      pos 6680
      pos 6688
    doc 11
      freq 40
      pos 1539
      pos 1544
      pos 2257
      pos 2262
      pos 3175
      pos 3180
      pos 3408
      pos 3413
      pos 4051
      pos 4056
      pos 4316
      pos 4321
      pos 4497
      pos 4502
      pos 4711
      pos 4716
      pos 5202
      pos 5207
      pos 5359
      pos 5364
      pos 5507
      pos 5512
      pos 5667
      pos 5672
      pos 5987
      pos 5992
      pos 6211
      pos 6216
      pos 6901
      pos 6905
      pos 7235
      pos 7240
      pos 8191
      pos 8196
      pos 8520
      pos 8525
      pos 9115
      pos 9120
      pos 9292
      pos 9297
  term ip6
    doc 12
      freq 3
      pos 782
      pos 5349
      pos 7163
  term ipcp
    doc 7
      freq 1
      pos 2097
  term ipng
    doc 4
      freq 2
      pos 5463
      pos 5467
  term ipop
    doc 11
      freq 1
      pos 9579
  term ippm
    doc 6
      freq 1
      pos 3023
  term ipr
    doc 0
      freq 4
      pos 17424
      pos 17476
      pos 17481
      pos 17524
    doc 1
      freq 4
      pos 9805
      pos 9857
      pos 9862
      pos 9905
    doc 2
      freq 4
      pos 6602
      pos 6654
      pos 6659
      pos 6702
    doc 3
      freq 4
      pos 6154
      pos 6206
      pos 6211
      pos 6254
    doc 4
      freq 4
      pos 6309
      pos 6361
      pos 6366
      pos 6409
    doc 5
      freq 4
      pos 4639
      pos 4691
      pos 4696
      pos 4739
    doc 6
      freq 4
      pos 3439
      pos 3491
      pos 3496
      pos 3539
    doc 7
      freq 4
      pos 3144
      pos 3196
      pos 3201
      pos 3244
    doc 8
      freq 4
      pos 2361
      pos 2413
      pos 2418
      pos 2461
    doc 9
      freq 4
      pos 2006
      pos 2058
      pos 2063
      pos 2106
    doc 10
      freq 4
      pos 13667
      pos 13719
      pos 13724
      pos 13767
    doc 11
      freq 4
      pos 10828
      pos 10880
      pos 10885
      pos 10928
    doc 12
      freq 4
      pos 9678
      pos 9730
      pos 9735
      pos 9778
    doc 13
      freq 4
      pos 7293
      pos 7345
      pos 7350
      pos 7393
    doc 14
      freq 4
      pos 5759
      pos 5811
      pos 5816
      pos 5859
    doc 15
      freq 4
      pos 4278
      pos 4330
      pos 4335
      pos 4378
    doc 16
      freq 4
      pos 2889
      pos 2941
      pos 2946
      pos 2989
    doc 17
      freq 4
      pos 2613
      pos 2665
      pos 2670
      pos 2713
    doc 18
      freq 4
      pos 2401
      pos 2453
      pos 2458
      pos 2501
    skipList 
      level 0
        skipDoc 7
        skipDocFP 1194385
        impacts 
          impact 
            freq 4
            norm 100
        impactsEnd 
        skipDoc 15
        skipDocFP 1195053
        impacts 
          impact 
            freq 4
            norm 95
        impactsEnd 
  term ipsec
    doc 0
      freq 1
      pos 16768
    doc 2
      freq 1
      pos 6149
    doc 4
      freq 3
      pos 4074
      pos 4648
      pos 5957
    doc 12
      freq 2
      pos 5157
      pos 7562
  term iptv
    doc 6
      freq 1
      pos 881
  term ipv4
    doc 0
      freq 17
      pos 2947
      pos 14450
      pos 14460
      pos 14474
      pos 14484
      pos 14510
      pos 14520
      pos 14616
      pos 14626
      pos 14640
      pos 14650
      pos 14676
      pos 14686
      pos 14700
      pos 14710
      pos 14724
      pos 14734
    doc 3
      freq 1
      pos 3412
    doc 4
      freq 3
      pos 298
      pos 577
      pos 1322
    doc 12
      freq 33
      pos 143
      pos 170
      pos 271
      pos 291
      pos 463
      pos 544
      pos 608
      pos 928
      pos 1069
      pos 1083
      pos 1107
      pos 1122
      pos 1132
      pos 1410
      pos 1534
      pos 1594
      pos 2293
      pos 2313
      pos 2362
      pos 2459
      pos 2777
      pos 2797
      pos 3182
      pos 3647
      pos 3752
      pos 4109
      pos 4153
      pos 4164
      pos 4358
      pos 7152
      pos 8049
      pos 8080
      pos 8754
    doc 15
      freq 62
      pos 30
      pos 81
      pos 93
      pos 115
      pos 327
      pos 370
      pos 441
      pos 484
      pos 518
      pos 567
      pos 586
      pos 609
      pos 619
      pos 667
      pos 686
      pos 695
      pos 711
      pos 777
      pos 801
      pos 811
      pos 1084
      pos 1088
      pos 1110
      pos 1213
      pos 1464
      pos 1569
      pos 1608
      pos 1636
      pos 1656
      pos 1816
      pos 1821
      pos 1937
      pos 1995
      pos 2068
      pos 2304
      pos 2335
      pos 2346
      pos 2355
      pos 2375
      pos 2405
      pos 2485
      pos 2635
      pos 2656
      pos 2691
      pos 2716
      pos 2737
      pos 2746
      pos 2754
      pos 2766
      pos 2769
      pos 2784
      pos 2871
      pos 2930
      pos 2973
      pos 3100
      pos 3325
      pos 3346
      pos 3392
      pos 3429
      pos 3571
      pos 3625
      pos 3753
  term ipv6
    doc 0
      freq 18
      pos 1696
      pos 2949
      pos 14452
      pos 14468
      pos 14476
      pos 14492
      pos 14512
      pos 14528
      pos 14618
      pos 14634
      pos 14642
      pos 14658
      pos 14678
      pos 14694
      pos 14702
      pos 14718
      pos 14726
      pos 14742
    doc 2
      freq 1
      pos 3113
    doc 3
      freq 1
      pos 3414
    doc 4
      freq 109
      pos 39
      pos 132
      pos 145
      pos 158
      pos 287
      pos 315
      pos 375
      pos 396
      pos 398
      pos 401
      pos 406
      pos 426
      pos 475
      pos 480
      pos 507
      pos 527
      pos 540
      pos 546
      pos 681
      pos 746
      pos 1015
      pos 1077
      pos 1081
      pos 1288
      pos 1294
      pos 1324
      pos 1372
      pos 1444
      pos 1465
      pos 1467
      pos 1548
      pos 1589
      pos 1591
      pos 1658
      pos 1667
      pos 1693
      pos 1708
      pos 1714
      pos 1759
      pos 1798
      pos 1802
      pos 1817
      pos 1838
      pos 2081
      pos 2146
      pos 2148
      pos 2149
      pos 2240
      pos 2318
      pos 2475
      pos 2722
      pos 2812
      pos 2814
      pos 2815
      pos 2941
      pos 2968
      pos 3057
      pos 3059
      pos 3060
      pos 3190
      pos 3205
      pos 3293
      pos 3295
      pos 3296
      pos 3328
      pos 3378
      pos 3391
      pos 3441
      pos 3494
      pos 3499
      pos 3589
      pos 3595
      pos 3631
      pos 3760
      pos 3803
      pos 3910
      pos 4041
      pos 4049
      pos 4068
      pos 4093
      pos 4118
      pos 4169
      pos 4172
      pos 4222
      pos 4230
      pos 4337
      pos 4341
      pos 4440
      pos 4503
      pos 4755
      pos 4792
      pos 4889
      pos 5031
      pos 5160
      pos 5176
      pos 5186
      pos 5192
      pos 5207
      pos 5244
      pos 5328
      pos 5339
      pos 5365
      pos 5382
      pos 5405
      pos 5408
      pos 5535
      pos 5820
      pos 6039
      pos 6105
    doc 9
      freq 7
      pos 19
      pos 171
      pos 766
      pos 792
      pos 1496
      pos 1502
      pos 1660
    doc 12
      freq 152
      pos 26
      pos 73
      pos 83
      pos 107
      pos 134
      pos 153
      pos 171
      pos 189
      pos 241
      pos 273
      pos 282
      pos 293
      pos 311
      pos 323
      pos 331
      pos 345
      pos 464
      pos 503
      pos 517
      pos 536
      pos 565
      pos 578
      pos 589
      pos 609
      pos 636
      pos 662
      pos 690
      pos 715
      pos 749
      pos 758
      pos 769
      pos 790
      pos 867
      pos 933
      pos 1076
      pos 1084
      pos 1109
      pos 1135
      pos 1225
      pos 1234
      pos 1241
      pos 1257
      pos 1387
      pos 1415
      pos 1511
      pos 1562
      pos 1588
      pos 1644
      pos 1658
      pos 1816
      pos 1822
      pos 1928
      pos 1947
      pos 2076
      pos 2085
      pos 2132
      pos 2281
      pos 2295
      pos 2315
      pos 2454
      pos 2511
      pos 2519
      pos 2574
      pos 2600
      pos 2612
      pos 2618
      pos 2626
      pos 2652
      pos 2667
      pos 2676
      pos 2699
      pos 2767
      pos 2799
      pos 3024
      pos 3160
      pos 3194
      pos 3222
      pos 3225
      pos 3252
      pos 3277
      pos 3293
      pos 3328
      pos 3337
      pos 3343
      pos 3360
      pos 3371
      pos 3388
      pos 3407
      pos 3426
      pos 3436
      pos 3612
      pos 3726
      pos 3734
      pos 3772
      pos 3790
      pos 3817
      pos 3862
      pos 3872
      pos 3916
      pos 3929
      pos 4081
      pos 4102
      pos 4113
      pos 4125
      pos 4136
      pos 4177
      pos 4199
      pos 4234
      pos 4360
      pos 4564
      pos 5015
      pos 5424
      pos 5860
      pos 6250
      pos 6506
      pos 6542
      pos 6643
      pos 6754
      pos 6843
      pos 6988
      pos 7078
      pos 7136
      pos 7149
      pos 7190
      pos 7213
      pos 7235
      pos 7254
      pos 7292
      pos 7309
      pos 7335
      pos 7362
      pos 7380
      pos 7398
      pos 7416
      pos 7442
      pos 7464
      pos 7581
      pos 7594
      pos 7612
      pos 7708
      pos 7730
      pos 7775
      pos 7801
      pos 7888
      pos 8081
      pos 8241
      pos 8638
      pos 8742
      pos 9050
      pos 9225
      pos 9422
      pos 9473
    doc 15
      freq 54
      pos 32
      pos 84
      pos 96
      pos 127
      pos 348
      pos 354
      pos 372
      pos 386
      pos 395
      pos 422
      pos 443
      pos 486
      pos 520
      pos 570
      pos 592
      pos 611
      pos 622
      pos 669
      pos 688
      pos 702
      pos 731
      pos 1064
      pos 1099
      pos 1112
      pos 1215
      pos 1364
      pos 1369
      pos 1418
      pos 1422
      pos 1443
      pos 1472
      pos 1545
      pos 1551
      pos 1613
      pos 1641
      pos 1658
      pos 1939
      pos 1997
      pos 2377
      pos 2487
      pos 2499
      pos 2687
      pos 2879
      pos 2941
      pos 2964
      pos 3083
      pos 3102
      pos 3374
      pos 3552
      pos 3567
      pos 3628
      pos 3915
      pos 3956
      pos 3973
  term ipx
    doc 7
      freq 5
      pos 689
      pos 1006
      pos 1985
      pos 2203
      pos 2493
  term ipxcp
    doc 7
      freq 1
      pos 1002
  term iqdwhnnxt83o9dmtbj4igttbrkdpyowkpq5weckq
    doc 10
      freq 1
      pos 12643
  term iqqphptb4b4qeixs2abs1olukgd8sohuncjbc3ojkspkkdvil9r3qf9odfgd
    doc 11
      freq 1
      pos 10347
  term irl
    doc 6
      freq 1
      pos 3160
  term irrespectiv
    doc 13
      freq 1
      pos 3952
  term is
    doc 0
      freq 579
      pos 26
      pos 27
      pos 78
      pos 123
      pos 124
      pos 129
      pos 157
      pos 158
      pos 187
      pos 188
      pos 274
      pos 280
      pos 315
      pos 316
      pos 327
      pos 382
      pos 383
      pos 452
      pos 453
      pos 474
      pos 475
      pos 488
      pos 489
      pos 541
      pos 542
      pos 570
      pos 605
      pos 606
      pos 611
      pos 662
      pos 663
      pos 716
      pos 717
      pos 823
      pos 824
      pos 946
      pos 947
      pos 995
      pos 996
      pos 1003
      pos 1004
      pos 1081
      pos 1082
      pos 1090
      pos 1091
      pos 1131
      pos 1132
      pos 1142
      pos 1158
      pos 1204
      pos 1205
      pos 1221
      pos 1402
      pos 1403
      pos 1452
      pos 1483
      pos 1519
      pos 1526
      pos 1545
      pos 1562
      pos 1614
      pos 1615
      pos 1642
      pos 1643
      pos 1668
      pos 1669
      pos 1730
      pos 1757
      pos 1780
      pos 1781
      pos 1832
      pos 1921
      pos 1922
      pos 2006
      pos 2007
      pos 2097
      pos 2098
      pos 2133
      pos 2144
      pos 2195
      pos 2243
      pos 2303
      pos 2304
      pos 2307
      pos 2329
      pos 2330
      pos 2344
      pos 2359
      pos 2402
      pos 2424
      pos 2487
      pos 2502
      pos 2539
      pos 2540
      pos 2720
      pos 2721
      pos 2750
      pos 2899
      pos 2900
      pos 2987
      pos 2998
      pos 2999
      pos 3003
      pos 3066
      pos 3087
      pos 3088
      pos 3100
      pos 3120
      pos 3121
      pos 3222
      pos 3248
      pos 3249
      pos 3265
      pos 3270
      pos 3284
      pos 3310
      pos 3459
      pos 3460
      pos 3508
      pos 3634
      pos 3671
      pos 3672
      pos 3758
      pos 3806
      pos 3807
      pos 3826
      pos 3828
      pos 3861
      pos 3902
      pos 3917
      pos 3997
      pos 4017
      pos 4018
      pos 4046
      pos 4066
      pos 4078
      pos 4150
      pos 4202
      pos 4203
      pos 4252
      pos 4326
      pos 4328
      pos 4361
      pos 4405
      pos 4406
      pos 4414
      pos 4429
      pos 4548
      pos 4549
      pos 4705
      pos 4706
      pos 4789
      pos 4821
      pos 4822
      pos 4886
      pos 4887
      pos 4888
      pos 4899
      pos 4900
      pos 4901
      pos 4907
      pos 4917
      pos 4942
      pos 5043
      pos 5044
      pos 5052
      pos 5058
      pos 5104
      pos 5113
      pos 5237
      pos 5238
      pos 5251
      pos 5267
      pos 5286
      pos 5314
      pos 5450
      pos 5451
      pos 5474
      pos 5475
      pos 5588
      pos 5589
      pos 5672
      pos 5673
      pos 5698
      pos 5713
      pos 5770
      pos 5771
      pos 5809
      pos 5810
      pos 5870
      pos 5878
      pos 5887
      pos 5888
      pos 5922
      pos 5926
      pos 5927
      pos 5951
      pos 5952
      pos 5963
      pos 5973
      pos 6063
      pos 6069
      pos 6179
      pos 6180
      pos 6198
      pos 6237
      pos 6242
      pos 6254
      pos 6291
      pos 6292
      pos 6319
      pos 6320
      pos 6344
      pos 6345
      pos 6434
      pos 6435
      pos 6530
      pos 6564
      pos 6579
      pos 6584
      pos 6590
      pos 6600
      pos 6633
      pos 6639
      pos 6654
      pos 6655
      pos 6671
      pos 6705
      pos 6749
      pos 6764
      pos 6792
      pos 6805
      pos 6824
      pos 6868
      pos 6908
      pos 6909
      pos 6954
      pos 6955
      pos 7087
      pos 7088
      pos 7128
      pos 7236
      pos 7237
      pos 7251
      pos 7252
      pos 7352
      pos 7353
      pos 7514
      pos 7515
      pos 7526
      pos 7592
      pos 7629
      pos 7679
      pos 7680
      pos 7790
      pos 7791
      pos 7818
      pos 7819
      pos 7952
      pos 7953
      pos 8060
      pos 8061
      pos 8101
      pos 8102
      pos 8136
      pos 8137
      pos 8155
      pos 8156
      pos 8192
      pos 8193
      pos 8227
      pos 8239
      pos 8245
      pos 8256
      pos 8257
      pos 8282
      pos 8283
      pos 8311
      pos 8312
      pos 8331
      pos 8332
      pos 8421
      pos 8422
      pos 8431
      pos 8432
      pos 8452
      pos 8453
      pos 8501
      pos 8521
      pos 8615
      pos 8616
      pos 8640
      pos 8641
      pos 8648
      pos 8649
      pos 8672
      pos 8673
      pos 8693
      pos 8694
      pos 8717
      pos 8718
      pos 8738
      pos 8739
      pos 8763
      pos 8764
      pos 8781
      pos 8782
      pos 8795
      pos 8802
      pos 8828
      pos 8829
      pos 8928
      pos 8929
      pos 8939
      pos 8951
      pos 8960
      pos 9080
      pos 9081
      pos 9186
      pos 9245
      pos 9246
      pos 9269
      pos 9368
      pos 9374
      pos 9439
      pos 9440
      pos 9554
      pos 9560
      pos 9595
      pos 9596
      pos 9739
      pos 9740
      pos 9779
      pos 9791
      pos 9797
      pos 9905
      pos 9906
      pos 10045
      pos 10046
      pos 10133
      pos 10148
      pos 10171
      pos 10172
      pos 10212
      pos 10291
      pos 10297
      pos 10325
      pos 10385
      pos 10386
      pos 10400
      pos 10443
      pos 10518
      pos 10584
      pos 10585
      pos 10643
      pos 10658
      pos 10686
      pos 10731
      pos 10738
      pos 10752
      pos 10768
      pos 10810
      pos 10811
      pos 10992
      pos 11022
      pos 11023
      pos 11096
      pos 11097
      pos 11121
      pos 11135
      pos 11190
      pos 11192
      pos 11225
      pos 11304
      pos 11305
      pos 11333
      pos 11432
      pos 11447
      pos 11485
      pos 11486
      pos 11544
      pos 11643
      pos 11644
      pos 11774
      pos 11775
      pos 11880
      pos 11881
      pos 11885
      pos 12051
      pos 12052
      pos 12178
      pos 12179
      pos 12276
      pos 12277
      pos 12281
      pos 12282
      pos 12314
      pos 12315
      pos 12467
      pos 12468
      pos 12519
      pos 12564
      pos 12639
      pos 12640
      pos 12692
      pos 12707
      pos 12717
      pos 12787
      pos 12788
      pos 12797
      pos 12818
      pos 12836
      pos 12848
      pos 12872
      pos 12889
      pos 12929
      pos 12953
      pos 12975
      pos 12992
      pos 12993
      pos 13143
      pos 13183
      pos 13184
      pos 13245
      pos 13342
      pos 13343
      pos 13462
      pos 13542
      pos 13543
      pos 13560
      pos 13611
      pos 13652
      pos 13701
      pos 13736
      pos 13737
      pos 13754
      pos 13804
      pos 13827
      pos 13878
      pos 13899
      pos 13926
      pos 13927
      pos 13964
      pos 13967
      pos 13979
      pos 14039
      pos 14090
      pos 14137
      pos 14138
      pos 14146
      pos 14153
      pos 14168
      pos 14234
      pos 14237
      pos 14261
      pos 14303
      pos 14324
      pos 14325
      pos 14338
      pos 14354
      pos 14398
      pos 14399
      pos 14501
      pos 14502
      pos 14564
      pos 14565
      pos 14667
      pos 14668
      pos 14769
      pos 14805
      pos 14806
      pos 14831
      pos 14843
      pos 14855
      pos 14867
      pos 14879
      pos 14891
      pos 14903
      pos 14915
      pos 14925
      pos 14926
      pos 14939
      pos 14951
      pos 14963
      pos 14975
      pos 14987
      pos 14999
      pos 15011
      pos 15023
      pos 15035
      pos 15052
      pos 15053
      pos 15059
      pos 15071
      pos 15083
      pos 15095
      pos 15107
      pos 15119
      pos 15131
      pos 15143
      pos 15155
      pos 15167
      pos 15179
      pos 15180
      pos 15191
      pos 15203
      pos 15215
      pos 15227
      pos 15239
      pos 15251
      pos 15263
      pos 15275
      pos 15287
      pos 15299
      pos 15309
      pos 15310
      pos 15323
      pos 15335
      pos 15347
      pos 15359
      pos 15371
      pos 15383
      pos 15395
      pos 15420
      pos 15421
      pos 15470
      pos 15471
      pos 15491
      pos 15492
      pos 15538
      pos 15539
      pos 15562
      pos 15563
      pos 15584
      pos 15585
      pos 15640
      pos 15641
      pos 15664
      pos 15724
      pos 15725
      pos 15801
      pos 15802
      pos 15841
      pos 15888
      pos 16006
      pos 16133
      pos 16134
      pos 16322
      pos 16323
      pos 16474
      pos 16475
      pos 16607
      pos 16608
      pos 16666
      pos 16712
      pos 16717
      pos 16762
      pos 16772
      pos 16782
      pos 16806
      pos 16811
      pos 16822
      pos 16845
      pos 16846
      pos 16855
      pos 16966
      pos 16967
      pos 17103
      pos 17104
      pos 17139
      pos 17140
      pos 17162
      pos 17163
      pos 17218
      pos 17219
      pos 17234
      pos 17270
      pos 17281
      pos 17533
    doc 1
      freq 200
      pos 95
      pos 140
      pos 329
      pos 340
      pos 443
      pos 485
      pos 507
      pos 590
      pos 645
      pos 851
      pos 894
      pos 916
      pos 1193
      pos 1218
      pos 1227
      pos 1262
      pos 1276
      pos 1303
      pos 1385
      pos 1392
      pos 1446
      pos 1508
      pos 1534
      pos 1550
      pos 1563
      pos 1584
      pos 1611
      pos 1638
      pos 1664
      pos 1677
      pos 1731
      pos 1819
      pos 1926
      pos 1968
      pos 1997
      pos 2029
      pos 2032
      pos 2043
      pos 2108
      pos 2136
      pos 2166
      pos 2437
      pos 2443
      pos 2446
      pos 2539
      pos 2599
      pos 2613
      pos 2640
      pos 2652
      pos 2705
      pos 2771
      pos 2791
      pos 2942
      pos 2980
      pos 3009
      pos 3032
      pos 3037
      pos 3148
      pos 3204
      pos 3236
      pos 3284
      pos 3503
      pos 3535
      pos 3555
      pos 3627
      pos 3632
      pos 3727
      pos 3833
      pos 4123
      pos 4137
      pos 4199
      pos 4216
      pos 4316
      pos 4438
      pos 4459
      pos 4501
      pos 4560
      pos 4571
      pos 4596
      pos 4617
      pos 4625
      pos 4715
      pos 4758
      pos 4828
      pos 4858
      pos 4897
      pos 4935
      pos 4975
      pos 4995
      pos 5063
      pos 5111
      pos 5177
      pos 5197
      pos 5213
      pos 5232
      pos 5308
      pos 5481
      pos 5486
      pos 5501
      pos 5508
      pos 5516
      pos 5533
      pos 5548
      pos 5557
      pos 5564
      pos 5573
      pos 5611
      pos 5629
      pos 5675
      pos 5759
      pos 5822
      pos 5840
      pos 5876
      pos 5938
      pos 6012
      pos 6099
      pos 6150
      pos 6171
      pos 6180
      pos 6188
      pos 6227
      pos 6244
      pos 6247
      pos 6259
      pos 6296
      pos 6329
      pos 6379
      pos 6385
      pos 6402
      pos 6425
      pos 6456
      pos 6474
      pos 6524
      pos 6548
      pos 6564
      pos 6575
      pos 6589
      pos 6604
      pos 6615
      pos 6622
      pos 6680
      pos 6687
      pos 6701
      pos 6717
      pos 6749
      pos 6774
      pos 6808
      pos 6815
      pos 6821
      pos 6913
      pos 6920
      pos 6974
      pos 6979
      pos 7062
      pos 7136
      pos 7141
      pos 7157
      pos 7164
      pos 7172
      pos 7187
      pos 7209
      pos 7224
      pos 7233
      pos 7239
      pos 7246
      pos 7256
      pos 7381
      pos 7449
      pos 7503
      pos 7512
      pos 7655
      pos 7663
      pos 7714
      pos 7951
      pos 8035
      pos 8042
      pos 8067
      pos 8108
      pos 8172
      pos 8246
      pos 8285
      pos 8303
      pos 8345
      pos 8358
      pos 8389
      pos 8401
      pos 8433
      pos 8446
      pos 8490
      pos 8537
      pos 8683
      pos 8744
      pos 8757
      pos 8760
      pos 8805
      pos 9466
      pos 9615
      pos 9651
      pos 9662
      pos 9914
    doc 2
      freq 41
      pos 48
      pos 599
      pos 740
      pos 909
      pos 923
      pos 957
      pos 974
      pos 1013
      pos 1020
      pos 1052
      pos 1057
      pos 1134
      pos 1151
      pos 1201
      pos 1230
      pos 1343
      pos 1546
      pos 1599
      pos 1609
      pos 1642
      pos 1650
      pos 1857
      pos 1897
      pos 1905
      pos 1963
      pos 1990
      pos 2139
      pos 2170
      pos 2191
      pos 3700
      pos 3713
      pos 3720
      pos 3788
      pos 3853
      pos 3938
      pos 3963
      pos 5396
      pos 6412
      pos 6448
      pos 6459
      pos 6711
    doc 3
      freq 103
      pos 89
      pos 104
      pos 426
      pos 438
      pos 650
      pos 836
      pos 945
      pos 976
      pos 1151
      pos 1163
      pos 1202
      pos 1383
      pos 1440
      pos 1494
      pos 1535
      pos 1549
      pos 1603
      pos 1725
      pos 1744
      pos 1800
      pos 1878
      pos 1982
      pos 1999
      pos 2038
      pos 2078
      pos 2102
      pos 2160
      pos 2175
      pos 2177
      pos 2189
      pos 2199
      pos 2207
      pos 2220
      pos 2243
      pos 2260
      pos 2266
      pos 2295
      pos 2298
      pos 2306
      pos 2317
      pos 2352
      pos 2376
      pos 2439
      pos 2460
      pos 2471
      pos 2474
      pos 2486
      pos 2505
      pos 2510
      pos 2532
      pos 2541
      pos 2598
      pos 2604
      pos 2700
      pos 2735
      pos 2848
      pos 2982
      pos 3006
      pos 3127
      pos 3134
      pos 3156
      pos 3271
      pos 3321
      pos 3327
      pos 3357
      pos 3378
      pos 3513
      pos 3523
      pos 3627
      pos 3741
      pos 3747
      pos 3759
      pos 3769
      pos 3777
      pos 3900
      pos 3918
      pos 4044
      pos 4072
      pos 4090
      pos 4137
      pos 4188
      pos 4223
      pos 4257
      pos 5020
      pos 5152
      pos 5215
      pos 5233
      pos 5251
      pos 5359
      pos 5460
      pos 5487
      pos 5504
      pos 5526
      pos 5572
      pos 5606
      pos 5633
      pos 5819
      pos 5824
      pos 5847
      pos 5964
      pos 6000
      pos 6011
      pos 6263
    doc 4
      freq 73
      pos 91
      pos 121
      pos 309
      pos 477
      pos 502
      pos 536
      pos 552
      pos 567
      pos 654
      pos 667
      pos 851
      pos 898
      pos 928
      pos 1028
      pos 1111
      pos 1140
      pos 1258
      pos 1306
      pos 1318
      pos 1338
      pos 1384
      pos 1424
      pos 1476
      pos 1494
      pos 1526
      pos 1543
      pos 1557
      pos 1595
      pos 1607
      pos 1877
      pos 1893
      pos 1940
      pos 1977
      pos 2003
      pos 2206
      pos 2274
      pos 2287
      pos 2302
      pos 2347
      pos 2357
      pos 2369
      pos 2373
      pos 2384
      pos 2400
      pos 2461
      pos 2500
      pos 2506
      pos 2605
      pos 2613
      pos 2626
      pos 2638
      pos 2645
      pos 2652
      pos 2689
      pos 2879
      pos 2893
      pos 2931
      pos 3093
      pos 3180
      pos 3361
      pos 4000
      pos 4475
      pos 4557
      pos 4578
      pos 4595
      pos 4739
      pos 4819
      pos 4904
      pos 5453
      pos 6119
      pos 6155
      pos 6166
      pos 6418
    doc 5
      freq 59
      pos 75
      pos 102
      pos 125
      pos 139
      pos 172
      pos 368
      pos 415
      pos 421
      pos 450
      pos 471
      pos 486
      pos 548
      pos 626
      pos 632
      pos 642
      pos 659
      pos 694
      pos 812
      pos 969
      pos 976
      pos 987
      pos 1039
      pos 1128
      pos 1286
      pos 1297
      pos 1445
      pos 1628
      pos 1666
      pos 1766
      pos 1995
      pos 2052
      pos 2068
      pos 2088
      pos 2114
      pos 2209
      pos 2219
      pos 2237
      pos 2259
      pos 2275
      pos 2430
      pos 2461
      pos 2478
      pos 2491
      pos 2505
      pos 2518
      pos 2601
      pos 2859
      pos 3027
      pos 3033
      pos 3172
      pos 3255
      pos 3410
      pos 3525
      pos 3574
      pos 3671
      pos 4449
      pos 4485
      pos 4496
      pos 4748
    doc 6
      freq 54
      pos 51
      pos 65
      pos 101
      pos 121
      pos 277
      pos 348
      pos 451
      pos 524
      pos 575
      pos 588
      pos 706
      pos 789
      pos 828
      pos 873
      pos 956
      pos 1003
      pos 1039
      pos 1167
      pos 1197
      pos 1247
      pos 1257
      pos 1301
      pos 1313
      pos 1333
      pos 1370
      pos 1414
      pos 1508
      pos 1632
      pos 1753
      pos 1763
      pos 1777
      pos 1785
      pos 1800
      pos 1819
      pos 1831
      pos 1913
      pos 1933
      pos 1956
      pos 1967
      pos 2004
      pos 2044
      pos 2086
      pos 2132
      pos 2175
      pos 2180
      pos 2248
      pos 2356
      pos 2373
      pos 2808
      pos 2859
      pos 3244
      pos 3285
      pos 3296
      pos 3548
    doc 7
      freq 20
      pos 62
      pos 239
      pos 391
      pos 644
      pos 1154
      pos 1218
      pos 1227
      pos 1257
      pos 1282
      pos 1345
      pos 1367
      pos 1415
      pos 1502
      pos 1590
      pos 1973
      pos 1974
      pos 2954
      pos 2990
      pos 3001
      pos 3253
    doc 8
      freq 16
      pos 56
      pos 272
      pos 369
      pos 585
      pos 608
      pos 950
      pos 986
      pos 1100
      pos 1163
      pos 1280
      pos 1344
      pos 1475
      pos 2171
      pos 2207
      pos 2218
      pos 2470
    doc 9
      freq 35
      pos 77
      pos 287
      pos 305
      pos 315
      pos 341
      pos 375
      pos 387
      pos 456
      pos 474
      pos 501
      pos 519
      pos 568
      pos 617
      pos 619
      pos 632
      pos 641
      pos 655
      pos 713
      pos 797
      pos 947
      pos 976
      pos 999
      pos 1135
      pos 1195
      pos 1212
      pos 1236
      pos 1273
      pos 1394
      pos 1561
      pos 1571
      pos 1587
      pos 1816
      pos 1852
      pos 1863
      pos 2115
    doc 10
      freq 221
      pos 80
      pos 433
      pos 569
      pos 585
      pos 639
      pos 721
      pos 851
      pos 912
      pos 941
      pos 1043
      pos 1168
      pos 1184
      pos 1409
      pos 1415
      pos 1429
      pos 1456
      pos 1487
      pos 1524
      pos 1553
      pos 1577
      pos 1593
      pos 1597
      pos 1629
      pos 1746
      pos 1763
      pos 1866
      pos 1873
      pos 1926
      pos 1964
      pos 1978
      pos 2206
      pos 2228
      pos 2255
      pos 2287
      pos 2410
      pos 2433
      pos 2455
      pos 2470
      pos 2535
      pos 2576
      pos 2633
      pos 2673
      pos 2732
      pos 2752
      pos 2797
      pos 2992
      pos 3014
      pos 3115
      pos 3155
      pos 3180
      pos 3217
      pos 3244
      pos 3396
      pos 3427
      pos 3471
      pos 3485
      pos 3511
      pos 3521
      pos 3546
      pos 3564
      pos 3627
      pos 3667
      pos 3699
      pos 3712
      pos 3740
      pos 3760
      pos 3848
      pos 3859
      pos 3867
      pos 3978
      pos 4009
      pos 4084
      pos 4105
      pos 4125
      pos 4168
      pos 4374
      pos 4386
      pos 4391
      pos 4439
      pos 4467
      pos 4558
      pos 4581
      pos 4794
      pos 4855
      pos 4956
      pos 4963
      pos 5089
      pos 5314
      pos 5388
      pos 5409
      pos 5428
      pos 5491
      pos 5547
      pos 5866
      pos 5910
      pos 5919
      pos 6087
      pos 6442
      pos 6466
      pos 6556
      pos 6592
      pos 7046
      pos 7107
      pos 7187
      pos 7216
      pos 7261
      pos 7308
      pos 7424
      pos 7476
      pos 7481
      pos 7514
      pos 7520
      pos 7536
      pos 7576
      pos 7578
      pos 7584
      pos 7654
      pos 7687
      pos 7708
      pos 7723
      pos 7737
      pos 7760
      pos 7776
      pos 7821
      pos 7826
      pos 7853
      pos 7861
      pos 7930
      pos 7932
      pos 8004
      pos 8048
      pos 8067
      pos 8110
      pos 8371
      pos 8429
      pos 8509
      pos 8596
      pos 8602
      pos 8613
      pos 8625
      pos 8636
      pos 8641
      pos 8712
      pos 8802
      pos 8952
      pos 9009
      pos 9039
      pos 9043
      pos 9063
      pos 9087
      pos 9100
      pos 9118
      pos 9133
      pos 9190
      pos 9279
      pos 9296
      pos 9418
      pos 9425
      pos 9448
      pos 9458
      pos 9509
      pos 9518
      pos 9591
      pos 9617
      pos 9650
      pos 9688
      pos 9766
      pos 9778
      pos 9872
      pos 10022
      pos 10086
      pos 10092
      pos 10163
      pos 10175
      pos 10193
      pos 10205
      pos 10274
      pos 10360
      pos 10401
      pos 10425
      pos 10562
      pos 10920
      pos 10957
      pos 11019
      pos 11058
      pos 11089
      pos 11093
      pos 11112
      pos 11146
      pos 11284
      pos 11308
      pos 11312
      pos 11349
      pos 11366
      pos 11495
      pos 11564
      pos 11570
      pos 11602
      pos 11652
      pos 11658
      pos 11679
      pos 11691
      pos 11697
      pos 11746
      pos 11752
      pos 11775
      pos 11798
      pos 11859
      pos 11865
      pos 11892
      pos 11943
      pos 11987
      pos 12025
      pos 12072
      pos 12189
      pos 12957
      pos 13044
      pos 13477
      pos 13513
      pos 13524
      pos 13776
    doc 11
      freq 102
      pos 64
      pos 168
      pos 562
      pos 565
      pos 716
      pos 763
      pos 780
      pos 899
      pos 980
      pos 1074
      pos 1619
      pos 1632
      pos 1637
      pos 1733
      pos 1773
      pos 1779
      pos 1830
      pos 2022
      pos 2047
      pos 2090
      pos 2100
      pos 2167
      pos 2316
      pos 2409
      pos 2425
      pos 2448
      pos 2451
      pos 2468
      pos 2474
      pos 2494
      pos 2618
      pos 2629
      pos 2661
      pos 2773
      pos 3294
      pos 3499
      pos 3708
      pos 3932
      pos 3968
      pos 4103
      pos 4252
      pos 4350
      pos 4359
      pos 4436
      pos 4573
      pos 4585
      pos 4762
      pos 4771
      pos 4777
      pos 4787
      pos 4970
      pos 4979
      pos 5084
      pos 5250
      pos 5262
      pos 5569
      pos 5580
      pos 5735
      pos 5746
      pos 5849
      pos 5860
      pos 5893
      pos 6038
      pos 6055
      pos 6141
      pos 6263
      pos 6297
      pos 6329
      pos 6389
      pos 6410
      pos 6498
      pos 6519
      pos 6648
      pos 6837
      pos 7343
      pos 7465
      pos 7495
      pos 7579
      pos 7621
      pos 7728
      pos 7802
      pos 7910
      pos 8019
      pos 8254
      pos 8303
      pos 8381
      pos 8397
      pos 8553
      pos 8710
      pos 8801
      pos 9037
      pos 9152
      pos 9179
      pos 9193
      pos 9213
      pos 9220
      pos 9235
      pos 9741
      pos 10638
      pos 10674
      pos 10685
      pos 10937
    doc 12
      freq 163
      pos 54
      pos 125
      pos 520
      pos 551
      pos 567
      pos 821
      pos 828
      pos 915
      pos 963
      pos 1009
      pos 1025
      pos 1058
      pos 1113
      pos 1150
      pos 1160
      pos 1370
      pos 1489
      pos 1504
      pos 1536
      pos 1585
      pos 1590
      pos 1608
      pos 1782
      pos 1792
      pos 1811
      pos 1837
      pos 1847
      pos 1897
      pos 2114
      pos 2128
      pos 2248
      pos 2309
      pos 2395
      pos 2432
      pos 2441
      pos 2456
      pos 2523
      pos 2546
      pos 2557
      pos 2565
      pos 2570
      pos 2582
      pos 2614
      pos 2622
      pos 2706
      pos 2728
      pos 2750
      pos 2952
      pos 3007
      pos 3030
      pos 3064
      pos 3078
      pos 3100
      pos 3156
      pos 3210
      pos 3226
      pos 3242
      pos 3267
      pos 3319
      pos 3479
      pos 3485
      pos 3543
      pos 3589
      pos 3691
      pos 3742
      pos 3757
      pos 3824
      pos 3838
      pos 3863
      pos 3875
      pos 3971
      pos 4008
      pos 4026
      pos 4050
      pos 4085
      pos 4090
      pos 4172
      pos 4230
      pos 4293
      pos 4326
      pos 4349
      pos 4353
      pos 4416
      pos 4440
      pos 4528
      pos 4573
      pos 4669
      pos 4765
      pos 4804
      pos 4816
      pos 4822
      pos 4905
      pos 5049
      pos 5105
      pos 5126
      pos 5176
      pos 5250
      pos 5381
      pos 5390
      pos 5402
      pos 5439
      pos 5495
      pos 5504
      pos 5572
      pos 5579
      pos 5599
      pos 5659
      pos 5712
      pos 5715
      pos 5813
      pos 5840
      pos 5888
      pos 5928
      pos 5959
      pos 6003
      pos 6037
      pos 6054
      pos 6059
      pos 6172
      pos 6181
      pos 6193
      pos 6198
      pos 6234
      pos 6268
      pos 6294
      pos 6306
      pos 6324
      pos 6399
      pos 6410
      pos 6437
      pos 6554
      pos 6588
      pos 6692
      pos 6700
      pos 6724
      pos 6856
      pos 7690
      pos 7991
      pos 8069
      pos 8102
      pos 8186
      pos 8373
      pos 8394
      pos 8405
      pos 8429
      pos 8450
      pos 8463
      pos 8500
      pos 8793
      pos 8973
      pos 8982
      pos 9029
      pos 9078
      pos 9119
      pos 9154
      pos 9164
      pos 9270
      pos 9321
      pos 9365
      pos 9488
      pos 9524
      pos 9535
      pos 9787
    doc 13
      freq 61
      pos 63
      pos 615
      pos 714
      pos 742
      pos 747
      pos 788
      pos 1220
      pos 1240
      pos 1343
      pos 1362
      pos 1600
      pos 1690
      pos 1702
      pos 1714
      pos 1758
      pos 1854
      pos 1913
      pos 1928
      pos 1964
      pos 2020
      pos 2033
      pos 2092
      pos 2204
      pos 2479
      pos 2554
      pos 2581
      pos 2686
      pos 2690
      pos 2761
      pos 2839
      pos 3075
      pos 3575
      pos 3836
      pos 3917
      pos 3946
      pos 4100
      pos 4161
      pos 4174
      pos 4238
      pos 4366
      pos 4499
      pos 4721
      pos 4818
      pos 4989
      pos 5034
      pos 5073
      pos 5087
      pos 5234
      pos 5306
      pos 5316
      pos 5404
      pos 5420
      pos 6054
      pos 6122
      pos 6616
      pos 6683
      pos 6728
      pos 7103
      pos 7139
      pos 7150
      pos 7402
    doc 14
      freq 56
      pos 58
      pos 299
      pos 308
      pos 406
      pos 484
      pos 534
      pos 547
      pos 653
      pos 699
      pos 732
      pos 791
      pos 896
      pos 914
      pos 951
      pos 968
      pos 1017
      pos 1074
      pos 1123
      pos 1161
      pos 1253
      pos 1294
      pos 1360
      pos 1393
      pos 1416
      pos 1468
      pos 1472
      pos 1496
      pos 1570
      pos 1593
      pos 1620
      pos 1669
      pos 1733
      pos 1899
      pos 1958
      pos 1968
      pos 1974
      pos 1990
      pos 1997
      pos 2299
      pos 2305
      pos 2333
      pos 2377
      pos 2897
      pos 2918
      pos 3852
      pos 4164
      pos 4234
      pos 4299
      pos 4421
      pos 4515
      pos 5030
      pos 5328
      pos 5569
      pos 5605
      pos 5616
      pos 5868
    doc 15
      freq 78
      pos 62
      pos 145
      pos 430
      pos 460
      pos 578
      pos 705
      pos 724
      pos 764
      pos 864
      pos 961
      pos 964
      pos 967
      pos 990
      pos 1073
      pos 1163
      pos 1180
      pos 1196
      pos 1198
      pos 1222
      pos 1272
      pos 1289
      pos 1330
      pos 1373
      pos 1403
      pos 1446
      pos 1482
      pos 1490
      pos 1682
      pos 1691
      pos 1778
      pos 1807
      pos 1830
      pos 1887
      pos 1984
      pos 2008
      pos 2015
      pos 2035
      pos 2119
      pos 2161
      pos 2182
      pos 2213
      pos 2216
      pos 2255
      pos 2308
      pos 2318
      pos 2365
      pos 2370
      pos 2538
      pos 2671
      pos 2721
      pos 2756
      pos 2800
      pos 2822
      pos 2855
      pos 2868
      pos 2873
      pos 2897
      pos 2925
      pos 3017
      pos 3035
      pos 3276
      pos 3304
      pos 3341
      pos 3394
      pos 3413
      pos 3487
      pos 3498
      pos 3525
      pos 3543
      pos 3554
      pos 3576
      pos 3661
      pos 3693
      pos 3735
      pos 4088
      pos 4124
      pos 4135
      pos 4387
    doc 16
      freq 35
      pos 76
      pos 448
      pos 693
      pos 708
      pos 719
      pos 736
      pos 746
      pos 762
      pos 834
      pos 840
      pos 920
      pos 927
      pos 938
      pos 954
      pos 962
      pos 976
      pos 992
      pos 1029
      pos 1060
      pos 1069
      pos 1094
      pos 1127
      pos 1139
      pos 1143
      pos 1254
      pos 1327
      pos 1465
      pos 1657
      pos 1904
      pos 1922
      pos 2282
      pos 2699
      pos 2735
      pos 2746
      pos 2998
    doc 17
      freq 44
      pos 73
      pos 111
      pos 226
      pos 303
      pos 368
      pos 459
      pos 502
      pos 611
      pos 637
      pos 659
      pos 663
      pos 707
      pos 721
      pos 725
      pos 747
      pos 765
      pos 785
      pos 930
      pos 956
      pos 1030
      pos 1063
      pos 1075
      pos 1093
      pos 1206
      pos 1266
      pos 1444
      pos 1567
      pos 1625
      pos 1635
      pos 1693
      pos 1788
      pos 1868
      pos 1904
      pos 1909
      pos 1915
      pos 1925
      pos 1949
      pos 1987
      pos 2164
      pos 2360
      pos 2423
      pos 2459
      pos 2470
      pos 2722
    doc 18
      freq 28
      pos 82
      pos 226
      pos 259
      pos 363
      pos 432
      pos 444
      pos 490
      pos 542
      pos 703
      pos 744
      pos 758
      pos 939
      pos 1099
      pos 1333
      pos 1549
      pos 1600
      pos 1751
      pos 1764
      pos 1772
      pos 1857
      pos 1908
      pos 1918
      pos 1951
      pos 1982
      pos 2211
      pos 2247
      pos 2258
      pos 2510
    skipList 
      level 0
        skipDoc 7
        skipDocFP 1204117
        impacts 
          impact 
            freq 20
            norm 100
          impact 
            freq 54
            norm 101
          impact 
            freq 59
            norm 104
          impact 
            freq 103
            norm 107
          impact 
            freq 200
            norm 113
          impact 
            freq 579
            norm 120
        impactsEnd 
        skipDoc 15
        skipDocFP 1221359
        impacts 
          impact 
            freq 35
            norm 95
          impact 
            freq 78
            norm 104
          impact 
            freq 163
            norm 113
          impact 
            freq 221
            norm 116
        impactsEnd 
  term isbn
    doc 11
      freq 1
      pos 7641
  term isdn
    doc 7
      freq 1
      pos 2545
  term iserver
    doc 16
      freq 1
      pos 897
  term ish
    doc 0
      freq 2
      pos 2636
      pos 8528
  term isig5r8kmjx
    doc 11
      freq 1
      pos 9897
  term isis
    doc 0
      freq 4
      pos 1006
      pos 1100
      pos 1102
      pos 11661
  term isis.ao
    doc 0
      freq 58
      pos 1488
      pos 2310
      pos 2375
      pos 2457
      pos 2518
      pos 2599
      pos 2651
      pos 2701
      pos 3127
      pos 3399
      pos 4798
      pos 4854
      pos 4955
      pos 5781
      pos 5816
      pos 6420
      pos 6490
      pos 6712
      pos 6771
      pos 6826
      pos 6920
      pos 6967
      pos 7007
      pos 7073
      pos 7142
      pos 7185
      pos 7370
      pos 7463
      pos 7493
      pos 7536
      pos 7563
      pos 7599
      pos 7646
      pos 7921
      pos 7958
      pos 8029
      pos 8079
      pos 8121
      pos 8487
      pos 8659
      pos 8704
      pos 8749
      pos 8789
      pos 8990
      pos 9068
      pos 9112
      pos 9138
      pos 9226
      pos 9282
      pos 9312
      pos 9427
      pos 10225
      pos 10460
      pos 10495
      pos 10529
      pos 10592
      pos 10702
      pos 10786
  term isisadjacencychang
    doc 0
      freq 2
      pos 14197
      pos 15652
  term isisadjstat
    doc 0
      freq 4
      pos 12627
      pos 14204
      pos 14236
      pos 15604
  term isisadminstat
    doc 0
      freq 10
      pos 1581
      pos 2242
      pos 2712
      pos 5486
      pos 5625
      pos 10051
      pos 10156
      pos 11057
      pos 11455
      pos 11475
  term isisadvancedcomplianc
    doc 0
      freq 1
      pos 14549
  term isisareaaddr
    doc 0
      freq 5
      pos 516
      pos 3445
      pos 3450
      pos 3464
      pos 15442
  term isisareaaddrentry
    doc 0
      freq 5
      pos 3354
      pos 3404
      pos 3408
      pos 3448
      pos 3485
  term isisareaaddrtabl
    doc 0
      freq 2
      pos 3348
      pos 3446
  term isisareamismatch
    doc 0
      freq 3
      pos 13681
      pos 13749
      pos 15647
  term isisattempttoexceedmaxsequenc
    doc 0
      freq 2
      pos 12999
      pos 15627
  term isisauthenticationfailur
    doc 0
      freq 3
      pos 13491
      pos 13555
      pos 15645
  term isisauthenticationtypefailur
    doc 0
      freq 3
      pos 13405
      pos 13457
      pos 15632
  term isiscirc
    doc 0
      freq 4
      pos 622
      pos 1301
      pos 5361
      pos 5427
  term isiscirc3wayenabled
    doc 0
      freq 6
      pos 5505
      pos 6186
      pos 6241
      pos 15255
      pos 15511
      pos 16266
  term isiscircadjchanges
    doc 0
      freq 3
      pos 7804
      pos 7895
      pos 15497
  term isiscircadminstat
    doc 0
      freq 5
      pos 5485
      pos 5621
      pos 15111
      pos 15480
      pos 16267
  term isiscircauthfails
    doc 0
      freq 3
      pos 7830
      pos 8175
      pos 15504
  term isiscircauthtypefails
    doc 0
      freq 3
      pos 7828
      pos 8126
      pos 15503
  term isiscircentry
    doc 0
      freq 21
      pos 5275
      pos 5324
      pos 5410
      pos 5429
      pos 5433
      pos 5442
      pos 5479
      pos 5574
      pos 5619
      pos 5641
      pos 5715
      pos 5784
      pos 5821
      pos 5898
      pos 5931
      pos 6014
      pos 6074
      pos 6128
      pos 6184
      pos 6208
      pos 6255
  term isiscircexiststat
    doc 0
      freq 5
      pos 5487
      pos 5643
      pos 15123
      pos 15481
      pos 16268
  term isiscircextdomain
    doc 0
      freq 5
      pos 5491
      pos 5786
      pos 15147
      pos 15483
      pos 16655
  term isiscircextendedcircid
    doc 0
      freq 5
      pos 5507
      pos 6210
      pos 15231
      pos 15512
      pos 16656
  term isiscircidfieldlenmismatches
    doc 0
      freq 3
      pos 7824
      pos 8034
      pos 15501
  term isiscircifindex
    doc 0
      freq 7
      pos 5483
      pos 5576
      pos 5779
      pos 14273
      pos 15243
      pos 15513
      pos 16657
  term isiscircindex
    doc 0
      freq 11
      pos 5464
      pos 5481
      pos 5509
      pos 6332
      pos 7796
      pos 8337
      pos 8880
      pos 9482
      pos 9665
      pos 9891
      pos 10028
  term isiscircinitfails
    doc 0
      freq 3
      pos 7808
      pos 7963
      pos 15499
  term isiscirclandesischanges
    doc 0
      freq 3
      pos 7832
      pos 8209
      pos 15505
  term isiscirclastuptim
    doc 0
      freq 3
      pos 5503
      pos 6130
      pos 15510
  term isiscirclevel
    doc 0
      freq 1
      pos 640
  term isiscirclevelcsnpinterval
    doc 0
      freq 5
      pos 6374
      pos 7092
      pos 15375
      pos 15525
      pos 16510
  term isiscircleveldesis
    doc 0
      freq 3
      pos 6362
      pos 6717
      pos 15519
  term isiscircleveldrhellotimer
    doc 0
      freq 5
      pos 6368
      pos 6927
      pos 15339
      pos 15522
      pos 16269
  term isiscirclevelentry
    doc 0
      freq 19
      pos 6276
      pos 6295
      pos 6299
      pos 6308
      pos 6336
      pos 6396
      pos 6425
      pos 6463
      pos 6495
      pos 6605
      pos 6715
      pos 6774
      pos 6831
      pos 6925
      pos 6972
      pos 7012
      pos 7078
      pos 7147
      pos 7190
  term isiscirclevelhellomultiplier
    doc 0
      freq 5
      pos 6364
      pos 6776
      pos 15315
      pos 15520
      pos 16658
  term isiscirclevelhellotimer
    doc 0
      freq 5
      pos 6366
      pos 6833
      pos 15327
      pos 15521
      pos 16270
  term isiscirclevelid
    doc 0
      freq 3
      pos 6360
      pos 6607
      pos 15518
  term isiscirclevelidoctet
    doc 0
      freq 5
      pos 6358
      pos 6497
      pos 6552
      pos 6683
      pos 15517
  term isiscirclevelindex
    doc 0
      freq 3
      pos 6333
      pos 6350
      pos 6378
  term isiscirclevelispriority
    doc 0
      freq 5
      pos 6356
      pos 6465
      pos 15291
      pos 15516
      pos 16599
  term isiscirclevellspthrottl
    doc 0
      freq 6
      pos 6370
      pos 6974
      pos 7051
      pos 15351
      pos 15523
      pos 16511
  term isiscirclevelmetric
    doc 0
      freq 5
      pos 6352
      pos 6398
      pos 15267
      pos 15514
      pos 16461
  term isiscirclevelminlspretransint
    doc 0
      freq 5
      pos 6372
      pos 7014
      pos 15363
      pos 15524
      pos 16512
  term isiscirclevelpartsnpinterval
    doc 0
      freq 5
      pos 6376
      pos 7149
      pos 15387
      pos 15526
      pos 16513
  term isiscircleveltabl
    doc 0
      freq 2
      pos 6270
      pos 6334
  term isiscircleveltyp
    doc 0
      freq 6
      pos 5493
      pos 5823
      pos 5874
      pos 15159
      pos 15496
      pos 16271
  term isiscirclevelvalues
    doc 0
      freq 2
      pos 1316
      pos 6293
  term isiscirclevelwidemetric
    doc 0
      freq 5
      pos 6354
      pos 6439
      pos 15279
      pos 15515
      pos 16462
  term isiscircmaxareaaddrmismatches
    doc 0
      freq 3
      pos 7826
      pos 8084
      pos 15502
  term isiscircmeshgroup
    doc 0
      freq 5
      pos 5499
      pos 6016
      pos 15207
      pos 15508
      pos 16570
  term isiscircmeshgroupenabled
    doc 0
      freq 6
      pos 5497
      pos 5933
      pos 6062
      pos 15195
      pos 15507
      pos 16571
  term isiscircnumadj
    doc 0
      freq 3
      pos 7806
      pos 7926
      pos 15498
  term isiscircpassivecircuit
    doc 0
      freq 6
      pos 5495
      pos 5900
      pos 15171
      pos 15506
      pos 16346
      pos 16515
  term isiscircrejadjs
    doc 0
      freq 4
      pos 7810
      pos 8001
      pos 8004
      pos 15500
  term isiscircsmallhellos
    doc 0
      freq 5
      pos 5501
      pos 6076
      pos 15219
      pos 15509
      pos 16272
  term isiscirctabl
    doc 0
      freq 4
      pos 5264
      pos 5298
      pos 5404
      pos 5465
  term isiscirctyp
    doc 0
      freq 5
      pos 5489
      pos 5717
      pos 15135
      pos 15482
      pos 16659
  term isiscircuitcounter
    doc 0
      freq 1
      pos 692
  term isiscircuitcounterentry
    doc 0
      freq 15
      pos 7752
      pos 7769
      pos 7773
      pos 7782
      pos 7800
      pos 7893
      pos 7924
      pos 7961
      pos 8002
      pos 8032
      pos 8082
      pos 8124
      pos 8173
      pos 8207
      pos 8247
  term isiscircuitcountertabl
    doc 0
      freq 3
      pos 7734
      pos 7746
      pos 7798
  term isiscircuitgroup
    doc 0
      freq 4
      pos 14536
      pos 14750
      pos 14820
      pos 15475
  term isiscircuitid
    doc 0
      freq 5
      pos 1970
      pos 6361
      pos 6363
      pos 6611
      pos 6721
  term isiscircuittyp
    doc 0
      freq 3
      pos 7797
      pos 7802
      pos 7834
  term isiscomplianc
    doc 0
      freq 1
      pos 14384
  term isiscompliances
    doc 0
      freq 4
      pos 14372
      pos 14540
      pos 14758
      pos 15398
  term isisconformanc
    doc 0
      freq 3
      pos 1266
      pos 14375
      pos 14380
  term isiscontrolpdussent
    doc 0
      freq 5
      pos 8488
      pos 8660
      pos 8705
      pos 8750
      pos 8790
  term isiscorruptedlspdetected
    doc 0
      freq 2
      pos 12918
      pos 15626
  term isiscounters
    doc 0
      freq 4
      pos 1325
      pos 7220
      pos 7767
      pos 8295
  term isisdatabaseoverload
    doc 0
      freq 2
      pos 12774
      pos 15624
  term isisdefaultmetric
    doc 0
      freq 9
      pos 1700
      pos 3689
      pos 3925
      pos 6353
      pos 6402
      pos 10057
      pos 10469
      pos 11059
      pos 11499
  term isiserroroffset
    doc 0
      freq 6
      pos 12668
      pos 14254
      pos 14295
      pos 14307
      pos 14343
      pos 15605
  term isiserrortlvtyp
    doc 0
      freq 4
      pos 12721
      pos 14255
      pos 14316
      pos 15606
  term isisfullmetric
    doc 0
      freq 5
      pos 1796
      pos 3691
      pos 3955
      pos 11063
      pos 11562
  term isisgroups
    doc 0
      freq 10
      pos 14377
      pos 15473
      pos 15541
      pos 15587
      pos 15618
      pos 15665
      pos 15690
      pos 15732
      pos 15761
      pos 15791
  term isishellotimer
    doc 0
      freq 3
      pos 6827
      pos 6921
      pos 6968
  term isisidlenmismatch
    doc 0
      freq 3
      pos 13070
      pos 13138
      pos 15628
  term isisipr
    doc 0
      freq 1
      pos 855
  term isisipraadminstat
    doc 0
      freq 4
      pos 11056
      pos 11451
      pos 15742
      pos 16463
  term isisipradest
    doc 0
      freq 5
      pos 11033
      pos 11042
      pos 11101
      pos 11173
      pos 11183
  term isisipradestprefixlen
    doc 0
      freq 6
      pos 10989
      pos 11034
      pos 11044
      pos 11146
      pos 11175
      pos 11213
  term isisipradestr
    doc 0
      freq 1
      pos 10988
  term isisipradesttyp
    doc 0
      freq 5
      pos 11032
      pos 11040
      pos 11068
      pos 11142
      pos 14697
  term isisipraentry
    doc 0
      freq 18
      pos 10888
      pos 10917
      pos 10921
      pos 11038
      pos 11087
      pos 11144
      pos 11240
      pos 11273
      pos 11295
      pos 11342
      pos 11398
      pos 11449
      pos 11493
      pos 11526
      pos 11556
      pos 11590
      pos 11634
      pos 11685
  term isisipraexiststat
    doc 0
      freq 4
      pos 11054
      pos 11400
      pos 15741
      pos 16464
  term isisiprafullmetric
    doc 0
      freq 4
      pos 11062
      pos 11558
      pos 15744
      pos 16465
  term isisiprametric
    doc 0
      freq 4
      pos 11058
      pos 11495
      pos 15743
      pos 16466
  term isisiprametrictyp
    doc 0
      freq 4
      pos 11060
      pos 11528
      pos 15745
      pos 16479
  term isisipranexthop
    doc 0
      freq 4
      pos 11050
      pos 11309
      pos 15739
      pos 16480
  term isisipranexthopindex
    doc 0
      freq 4
      pos 10991
      pos 11035
      pos 11046
      pos 11242
  term isisipranexthoptyp
    doc 0
      freq 6
      pos 11048
      pos 11275
      pos 11340
      pos 14721
      pos 15738
      pos 16481
  term isisiprasnpaaddress
    doc 0
      freq 4
      pos 11064
      pos 11592
      pos 15746
      pos 16482
  term isisiprasourcetyp
    doc 0
      freq 3
      pos 11066
      pos 11648
      pos 15747
  term isisipratabl
    doc 0
      freq 2
      pos 10882
      pos 11036
  term isisipratyp
    doc 0
      freq 4
      pos 11052
      pos 11344
      pos 15740
      pos 16483
  term isisipreachaddr
    doc 0
      freq 2
      pos 1365
      pos 10915
  term isisisadj
    doc 0
      freq 6
      pos 730
      pos 1337
      pos 8843
      pos 9430
      pos 9625
      pos 9850
  term isisisadj3waystat
    doc 0
      freq 3
      pos 8890
      pos 8995
      pos 15548
  term isisisadjareaaddr
    doc 0
      freq 1
      pos 760
  term isisisadjareaaddrentry
    doc 0
      freq 6
      pos 9400
      pos 9444
      pos 9448
      pos 9487
      pos 9525
      pos 9551
  term isisisadjareaaddress
    doc 0
      freq 3
      pos 9491
      pos 9527
      pos 15569
  term isisisadjareaaddrindex
    doc 0
      freq 3
      pos 9484
      pos 9489
      pos 9493
  term isisisadjareaaddrtabl
    doc 0
      freq 2
      pos 9394
      pos 9485
  term isisisadjentry
    doc 0
      freq 15
      pos 8816
      pos 8845
      pos 8849
      pos 8884
      pos 8962
      pos 8993
      pos 9046
      pos 9071
      pos 9115
      pos 9141
      pos 9171
      pos 9229
      pos 9285
      pos 9315
      pos 9365
  term isisisadjgroup
    doc 0
      freq 4
      pos 14537
      pos 14751
      pos 14821
      pos 15543
  term isisisadjholdtimer
    doc 0
      freq 3
      pos 8902
      pos 9231
      pos 15554
  term isisisadjindex
    doc 0
      freq 6
      pos 8881
      pos 8886
      pos 8908
      pos 9483
      pos 9666
      pos 9892
  term isisisadjipaddr
    doc 0
      freq 1
      pos 778
  term isisisadjipaddraddress
    doc 0
      freq 3
      pos 9676
      pos 9750
      pos 15571
  term isisisadjipaddrentry
    doc 0
      freq 7
      pos 9587
      pos 9627
      pos 9631
      pos 9670
      pos 9707
      pos 9748
      pos 9788
  term isisisadjipaddrindex
    doc 0
      freq 3
      pos 9667
      pos 9672
      pos 9678
  term isisisadjipaddrtabl
    doc 0
      freq 2
      pos 9581
      pos 9668
  term isisisadjipaddrtyp
    doc 0
      freq 6
      pos 9674
      pos 9709
      pos 9786
      pos 14507
      pos 14673
      pos 15570
  term isisisadjlastuptim
    doc 0
      freq 3
      pos 8906
      pos 9317
      pos 15568
  term isisisadjnbrextendedcircid
    doc 0
      freq 3
      pos 8898
      pos 9143
      pos 15552
  term isisisadjneighpriority
    doc 0
      freq 3
      pos 8904
      pos 9287
      pos 15567
  term isisisadjneighsnpaaddress
    doc 0
      freq 3
      pos 8892
      pos 9048
      pos 15549
  term isisisadjneighsysid
    doc 0
      freq 3
      pos 8896
      pos 9117
      pos 15551
  term isisisadjneighsystyp
    doc 0
      freq 3
      pos 8894
      pos 9085
      pos 15550
  term isisisadjprotsupp
    doc 0
      freq 1
      pos 797
  term isisisadjprotsuppentry
    doc 0
      freq 5
      pos 9824
      pos 9852
      pos 9856
      pos 9896
      pos 9936
  term isisisadjprotsuppprotocol
    doc 0
      freq 4
      pos 9893
      pos 9910
      pos 9912
      pos 15572
  term isisisadjprotsupptabl
    doc 0
      freq 2
      pos 9818
      pos 9894
  term isisisadjstat
    doc 0
      freq 4
      pos 8888
      pos 8964
      pos 9042
      pos 15547
  term isisisadjtabl
    doc 0
      freq 2
      pos 8810
      pos 8882
  term isisisadjusag
    doc 0
      freq 3
      pos 8900
      pos 9173
      pos 15553
  term isisisipradestgroup
    doc 0
      freq 2
      pos 14756
      pos 15734
  term isisislevel
    doc 0
      freq 13
      pos 1883
      pos 4517
      pos 4559
      pos 4715
      pos 4736
      pos 6351
      pos 6382
      pos 7258
      pos 7287
      pos 8345
      pos 8366
      pos 11781
      pos 11800
  term isisispducountergroup
    doc 0
      freq 2
      pos 14754
      pos 15667
  term isisispriority
    doc 0
      freq 5
      pos 1993
      pos 6357
      pos 6469
      pos 8905
      pos 9291
  term isislevel
    doc 0
      freq 7
      pos 1909
      pos 2321
      pos 5494
      pos 5827
      pos 8901
      pos 9177
      pos 12301
  term isislevelstat
    doc 0
      freq 3
      pos 1633
      pos 4721
      pos 4865
  term isislinkstatepduid
    doc 0
      freq 4
      pos 1496
      pos 11783
      pos 11821
      pos 12360
  term isislspattributes
    doc 0
      freq 3
      pos 11794
      pos 11960
      pos 15772
  term isislspbuffsiz
    doc 0
      freq 3
      pos 1601
      pos 4717
      pos 4756
  term isislspchecksum
    doc 0
      freq 3
      pos 11788
      pos 11895
      pos 15769
  term isislspdatabas
    doc 0
      freq 3
      pos 1381
      pos 11725
      pos 12064
  term isislsperrordetected
    doc 0
      freq 2
      pos 14246
      pos 15653
  term isislspgroup
    doc 0
      freq 2
      pos 14757
      pos 15763
  term isislspid
    doc 0
      freq 4
      pos 11763
      pos 11782
      pos 11817
      pos 12102
  term isislsplevel
    doc 0
      freq 4
      pos 11762
      pos 11780
      pos 11796
      pos 12101
  term isislsplifetimeremain
    doc 0
      freq 3
      pos 11790
      pos 11917
      pos 15770
  term isislsppdulength
    doc 0
      freq 3
      pos 11792
      pos 11941
      pos 15771
  term isislspseq
    doc 0
      freq 3
      pos 11784
      pos 11841
      pos 15767
  term isislspsummaryentry
    doc 0
      freq 12
      pos 11712
      pos 11727
      pos 11731
      pos 11766
      pos 11815
      pos 11839
      pos 11859
      pos 11893
      pos 11915
      pos 11939
      pos 11958
      pos 11977
  term isislspsummarytabl
    doc 0
      freq 3
      pos 887
      pos 11706
      pos 11764
  term isislsptlvchecksum
    doc 0
      freq 3
      pos 12112
      pos 12192
      pos 15774
  term isislsptlventry
    doc 0
      freq 10
      pos 12037
      pos 12066
      pos 12070
      pos 12106
      pos 12158
      pos 12190
      pos 12212
      pos 12231
      pos 12250
      pos 12273
  term isislsptlvindex
    doc 0
      freq 3
      pos 12103
      pos 12108
      pos 12121
  term isislsptlvlen
    doc 0
      freq 3
      pos 12116
      pos 12233
      pos 15776
  term isislsptlvseq
    doc 0
      freq 3
      pos 12110
      pos 12160
      pos 15773
  term isislsptlvtabl
    doc 0
      freq 3
      pos 910
      pos 12031
      pos 12104
  term isislsptlvtyp
    doc 0
      freq 3
      pos 12114
      pos 12214
      pos 15775
  term isislsptlvvalu
    doc 0
      freq 3
      pos 12118
      pos 12252
      pos 15777
  term isislsptoolargetopropagat
    doc 0
      freq 3
      pos 13856
      pos 13894
      pos 15649
  term isislspzerolif
    doc 0
      freq 3
      pos 11786
      pos 11861
      pos 15768
  term isismanareaaddr
    doc 0
      freq 4
      pos 493
      pos 3164
      pos 3169
      pos 3173
  term isismanareaaddrentry
    doc 0
      freq 9
      pos 3037
      pos 3111
      pos 3132
      pos 3136
      pos 3167
      pos 3227
      pos 3257
      pos 3287
      pos 3312
  term isismanareaaddrexiststat
    doc 0
      freq 7
      pos 3065
      pos 3095
      pos 3171
      pos 3229
      pos 14943
      pos 15430
      pos 16312
  term isismanareaaddrtabl
    doc 0
      freq 2
      pos 3031
      pos 3165
  term isismanualaddressdrops
    doc 0
      freq 3
      pos 12826
      pos 12884
      pos 15625
  term isismaxareaaddressesmismatch
    doc 0
      freq 3
      pos 13172
      pos 13240
      pos 15629
  term isismetricstyl
    doc 0
      freq 5
      pos 1852
      pos 4727
      pos 4729
      pos 5141
      pos 5170
  term isismetrictyp
    doc 0
      freq 5
      pos 1826
      pos 10059
      pos 10506
      pos 11061
      pos 11532
  term isismib
    doc 0
      freq 5
      pos 1069
      pos 1259
      pos 1264
      pos 1269
      pos 15833
  term isisnextcircindex
    doc 0
      freq 4
      pos 608
      pos 5225
      pos 5537
      pos 15479
  term isisnotification
    doc 0
      freq 3
      pos 935
      pos 1390
      pos 12295
  term isisnotificationareaaddress
    doc 0
      freq 4
      pos 12744
      pos 12830
      pos 12855
      pos 15607
  term isisnotificationcircifindex
    doc 0
      freq 16
      pos 12330
      pos 13076
      pos 13190
      pos 13279
      pos 13331
      pos 13410
      pos 13496
      pos 13594
      pos 13685
      pos 13788
      pos 13861
      pos 13945
      pos 14073
      pos 14202
      pos 14252
      pos 15594
  term isisnotificationentry
    doc 0
      freq 16
      pos 12292
      pos 12328
      pos 12354
      pos 12379
      pos 12407
      pos 12432
      pos 12458
      pos 12494
      pos 12524
      pos 12568
      pos 12593
      pos 12625
      pos 12666
      pos 12719
      pos 12742
      pos 12760
  term isisnotificationgroup
    doc 0
      freq 3
      pos 14539
      pos 14753
      pos 15620
  term isisnotificationobjectgroup
    doc 0
      freq 3
      pos 14538
      pos 14752
      pos 15589
  term isisnotifications
    doc 0
      freq 19
      pos 1256
      pos 12824
      pos 12916
      pos 12997
      pos 13068
      pos 13170
      pos 13272
      pos 13324
      pos 13403
      pos 13489
      pos 13587
      pos 13679
      pos 13781
      pos 13854
      pos 13938
      pos 14066
      pos 14195
      pos 14244
      pos 14358
  term isisnotificationsyslevelindex
    doc 0
      freq 18
      pos 12297
      pos 12778
      pos 12922
      pos 13003
      pos 13074
      pos 13188
      pos 13278
      pos 13330
      pos 13409
      pos 13495
      pos 13593
      pos 13787
      pos 13860
      pos 13944
      pos 14072
      pos 14201
      pos 14250
      pos 15593
  term isisobjects
    doc 0
      freq 11
      pos 1261
      pos 1280
      pos 1294
      pos 1304
      pos 1319
      pos 1328
      pos 1340
      pos 1351
      pos 1368
      pos 1384
      pos 1393
  term isisoriglspbuffsizemismatch
    doc 0
      freq 3
      pos 13940
      pos 14034
      pos 15650
  term isisosinsaddress
    doc 0
      freq 20
      pos 1409
      pos 3170
      pos 3177
      pos 3451
      pos 3468
      pos 8893
      pos 9052
      pos 9492
      pos 9531
      pos 10053
      pos 10061
      pos 10063
      pos 10065
      pos 10197
      pos 10540
      pos 10616
      pos 10714
      pos 11065
      pos 11596
      pos 12748
  term isisownlsppurg
    doc 0
      freq 2
      pos 13274
      pos 15630
  term isispacketcountcsnp
    doc 0
      freq 3
      pos 8356
      pos 8664
      pos 15675
  term isispacketcountdirection
    doc 0
      freq 3
      pos 8339
      pos 8346
      pos 8386
  term isispacketcounter
    doc 0
      freq 1
      pos 713
  term isispacketcounterentry
    doc 0
      freq 13
      pos 8272
      pos 8297
      pos 8301
      pos 8342
      pos 8384
      pos 8409
      pos 8490
      pos 8548
      pos 8605
      pos 8662
      pos 8707
      pos 8752
      pos 8792
  term isispacketcountertabl
    doc 0
      freq 3
      pos 8249
      pos 8266
      pos 8340
  term isispacketcounteshell
    doc 0
      freq 3
      pos 8352
      pos 8550
      pos 15673
  term isispacketcountiihell
    doc 0
      freq 3
      pos 8348
      pos 8411
      pos 15671
  term isispacketcountishell
    doc 0
      freq 3
      pos 8350
      pos 8492
      pos 15672
  term isispacketcountlevel
    doc 0
      freq 3
      pos 8338
      pos 8344
      pos 8362
  term isispacketcountlsp
    doc 0
      freq 3
      pos 8354
      pos 8607
      pos 15674
  term isispacketcountpsnp
    doc 0
      freq 3
      pos 8358
      pos 8709
      pos 15676
  term isispacketcountunknown
    doc 0
      freq 3
      pos 8360
      pos 8754
      pos 15677
  term isispdubuffersiz
    doc 0
      freq 3
      pos 12570
      pos 13948
      pos 15602
  term isispdufieldlen
    doc 0
      freq 3
      pos 12409
      pos 13075
      pos 15597
  term isispdufragment
    doc 0
      freq 12
      pos 12381
      pos 13077
      pos 13191
      pos 13411
      pos 13497
      pos 13596
      pos 13686
      pos 13789
      pos 14076
      pos 14253
      pos 14286
      pos 15596
  term isispduheader
    doc 0
      freq 2
      pos 1949
      pos 12385
  term isispdulspid
    doc 0
      freq 12
      pos 12356
      pos 12923
      pos 13004
      pos 13280
      pos 13332
      pos 13863
      pos 13946
      pos 14075
      pos 14203
      pos 14227
      pos 14251
      pos 15595
  term isispdulspsiz
    doc 0
      freq 3
      pos 12496
      pos 13862
      pos 15600
  term isispdumaxareaaddress
    doc 0
      freq 3
      pos 12434
      pos 13189
      pos 15598
  term isispduoriginatingbuffersiz
    doc 0
      freq 3
      pos 12526
      pos 13947
      pos 15601
  term isispduprotocolssupported
    doc 0
      freq 3
      pos 12595
      pos 14074
      pos 15603
  term isispduprotocolversion
    doc 0
      freq 3
      pos 12472
      pos 13595
      pos 15599
  term isisprotocolssupportedmismatch
    doc 0
      freq 3
      pos 14068
      pos 14163
      pos 15651
  term isisr
    doc 0
      freq 1
      pos 832
  term isisraaddrprefix
    doc 0
      freq 4
      pos 10052
      pos 10193
      pos 15698
      pos 16630
  term isisraadminstat
    doc 0
      freq 4
      pos 10050
      pos 10152
      pos 15697
      pos 16631
  term isisraentry
    doc 0
      freq 16
      pos 9974
      pos 9994
      pos 9998
      pos 10032
      pos 10086
      pos 10101
      pos 10150
      pos 10191
      pos 10228
      pos 10463
      pos 10500
      pos 10534
      pos 10610
      pos 10708
      pos 10792
      pos 10856
  term isisraexiststat
    doc 0
      freq 4
      pos 10036
      pos 10103
      pos 15696
      pos 16632
  term isisraindex
    doc 0
      freq 3
      pos 10029
      pos 10034
      pos 10068
  term isisramaptyp
    doc 0
      freq 5
      pos 10054
      pos 10230
      pos 10730
      pos 15699
      pos 16633
  term isisrametric
    doc 0
      freq 4
      pos 10056
      pos 10465
      pos 15700
      pos 16634
  term isisrametrictyp
    doc 0
      freq 4
      pos 10058
      pos 10502
      pos 15701
      pos 16635
  term isisrasnpaaddress
    doc 0
      freq 5
      pos 10060
      pos 10317
      pos 10536
      pos 15702
      pos 16636
  term isisrasnpamask
    doc 0
      freq 7
      pos 10062
      pos 10426
      pos 10612
      pos 10655
      pos 10671
      pos 15703
      pos 16637
  term isisrasnpaprefix
    doc 0
      freq 5
      pos 10064
      pos 10447
      pos 10710
      pos 15704
      pos 16638
  term isisratabl
    doc 0
      freq 2
      pos 9968
      pos 10030
  term isisratablegroup
    doc 0
      freq 2
      pos 14755
      pos 15692
  term isisratyp
    doc 0
      freq 4
      pos 10066
      pos 10794
      pos 15705
      pos 16639
  term isisreachaddr
    doc 0
      freq 2
      pos 1348
      pos 9992
  term isisreadonlycomplianc
    doc 0
      freq 1
      pos 14760
  term isisredistributeaddr
    doc 0
      freq 1
      pos 548
  term isisredistributeaddraddress
    doc 0
      freq 6
      pos 4147
      pos 4178
      pos 4186
      pos 4227
      pos 4309
      pos 4319
  term isisredistributeaddrentry
    doc 0
      freq 8
      pos 4005
      pos 4095
      pos 4099
      pos 4182
      pos 4225
      pos 4279
      pos 4376
      pos 4431
  term isisredistributeaddrexiststat
    doc 0
      freq 5
      pos 4190
      pos 4378
      pos 15099
      pos 15444
      pos 16484
  term isisredistributeaddrprefixlen
    doc 0
      freq 7
      pos 4149
      pos 4179
      pos 4188
      pos 4278
      pos 4281
      pos 4311
      pos 4349
  term isisredistributeaddrtabl
    doc 0
      freq 2
      pos 3999
      pos 4180
  term isisredistributeaddrtyp
    doc 0
      freq 6
      pos 4177
      pos 4184
      pos 4192
      pos 4259
      pos 14471
      pos 14637
  term isisrejectedadjacency
    doc 0
      freq 3
      pos 13783
      pos 13822
      pos 15648
  term isisrouter
    doc 0
      freq 1
      pos 572
  term isisrouterentry
    doc 0
      freq 8
      pos 4458
      pos 4475
      pos 4479
      pos 4512
      pos 4553
      pos 4579
      pos 4606
      pos 4631
  term isisrouterhostnam
    doc 0
      freq 3
      pos 4518
      pos 4581
      pos 15445
  term isisrouterid
    doc 0
      freq 3
      pos 4520
      pos 4608
      pos 15446
  term isisrouterlevel
    doc 0
      freq 3
      pos 4509
      pos 4516
      pos 4555
  term isisroutersysid
    doc 0
      freq 3
      pos 4508
      pos 4514
      pos 4522
  term isisroutertabl
    doc 0
      freq 2
      pos 4452
      pos 4510
  term isissequencenumberskip
    doc 0
      freq 2
      pos 13326
      pos 15631
  term isissummaddr
    doc 0
      freq 1
      pos 527
  term isissummaddrentry
    doc 0
      freq 10
      pos 3523
      pos 3587
      pos 3591
      pos 3678
      pos 3713
      pos 3767
      pos 3876
      pos 3919
      pos 3949
      pos 3980
  term isissummaddress
    doc 0
      freq 6
      pos 3631
      pos 3662
      pos 3682
      pos 3715
      pos 3797
      pos 3819
  term isissummaddresstyp
    doc 0
      freq 6
      pos 3661
      pos 3680
      pos 3692
      pos 3765
      pos 14447
      pos 14613
  term isissummaddrexiststat
    doc 0
      freq 5
      pos 3686
      pos 3878
      pos 15063
      pos 15440
      pos 16485
  term isissummaddrfullmetric
    doc 0
      freq 5
      pos 3690
      pos 3951
      pos 15087
      pos 15443
      pos 16486
  term isissummaddrmetric
    doc 0
      freq 5
      pos 3688
      pos 3921
      pos 15075
      pos 15441
      pos 16487
  term isissummaddrprefixlen
    doc 0
      freq 7
      pos 3633
      pos 3663
      pos 3684
      pos 3752
      pos 3769
      pos 3811
      pos 3849
  term isissummaddrtabl
    doc 0
      freq 2
      pos 3517
      pos 3676
  term isissupportedprotocol
    doc 0
      freq 3
      pos 1655
      pos 9911
      pos 9916
  term isissysadminstat
    doc 0
      freq 9
      pos 2357
      pos 2500
      pos 2708
      pos 3260
      pos 4787
      pos 5065
      pos 14895
      pos 15425
      pos 16313
  term isissyscorrlsps
    doc 0
      freq 1
      pos 12956
  term isissysid
    doc 0
      freq 5
      pos 2382
      pos 14835
      pos 15408
      pos 16314
      pos 16410
  term isissysl2tol1leaking
    doc 0
      freq 7
      pos 2767
      pos 3996
      pos 4065
      pos 14907
      pos 15426
      pos 16409
      pos 16488
  term isissyslevel
    doc 0
      freq 3
      pos 587
      pos 1291
      pos 4666
  term isissyslevelentry
    doc 0
      freq 13
      pos 4652
      pos 4668
      pos 4672
      pos 4712
      pos 4750
      pos 4803
      pos 4859
      pos 4958
      pos 5015
      pos 5135
      pos 5164
      pos 5194
      pos 5218
  term isissyslevelindex
    doc 0
      freq 4
      pos 4697
      pos 4714
      pos 4732
      pos 11031
  term isissyslevelmetricstyl
    doc 0
      freq 5
      pos 4726
      pos 5137
      pos 15003
      pos 15436
      pos 16374
  term isissyslevelminlspgenint
    doc 0
      freq 6
      pos 2580
      pos 4718
      pos 4805
      pos 14967
      pos 15432
      pos 16404
  term isissysleveloriglspbuffsiz
    doc 0
      freq 10
      pos 2887
      pos 2928
      pos 4716
      pos 4752
      pos 12545
      pos 13974
      pos 14003
      pos 14955
      pos 15431
      pos 16375
  term isissyslevelsetoverload
    doc 0
      freq 8
      pos 4722
      pos 4938
      pos 4960
      pos 5109
      pos 5112
      pos 14979
      pos 15434
      pos 16405
  term isissyslevelsetoverloaduntil
    doc 0
      freq 9
      pos 4724
      pos 5011
      pos 5017
      pos 5081
      pos 5084
      pos 5122
      pos 14991
      pos 15435
      pos 16406
  term isissyslevelspfconsiders
    doc 0
      freq 5
      pos 4728
      pos 5166
      pos 15015
      pos 15437
      pos 16376
  term isissyslevelstat
    doc 0
      freq 4
      pos 4720
      pos 4861
      pos 12779
      pos 15433
  term isissysleveltabl
    doc 0
      freq 2
      pos 4646
      pos 4710
  term isissyslevelteenabled
    doc 0
      freq 5
      pos 4730
      pos 5196
      pos 15027
      pos 15438
      pos 16377
  term isissysleveltyp
    doc 0
      freq 5
      pos 2317
      pos 5865
      pos 14823
      pos 15407
      pos 16311
  term isissysmaxag
    doc 0
      freq 5
      pos 2590
      pos 2801
      pos 14931
      pos 15427
      pos 16407
  term isissysmaxlspgenint
    doc 0
      freq 5
      pos 2525
      pos 2837
      pos 14859
      pos 15410
      pos 16408
  term isissysmaxpathsplits
    doc 0
      freq 4
      pos 2462
      pos 14847
      pos 15409
      pos 16460
  term isissysnotificationenabl
    doc 0
      freq 4
      pos 2972
      pos 12772
      pos 15429
      pos 16543
  term isissysobject
    doc 0
      freq 14
      pos 2277
      pos 2315
      pos 2380
      pos 2460
      pos 2523
      pos 2604
      pos 2656
      pos 2706
      pos 2765
      pos 2799
      pos 2847
      pos 2938
      pos 2970
      pos 3022
  term isissyspolleshellorat
    doc 0
      freq 4
      pos 2606
      pos 14871
      pos 15411
      pos 16640
  term isissysprotsupported
    doc 0
      freq 2
      pos 2940
      pos 15428
  term isissysreceivelspbuffersiz
    doc 0
      freq 5
      pos 2849
      pos 2915
      pos 15039
      pos 15439
      pos 16378
  term isissysstatattmpttoexmaxseqnums
    doc 0
      freq 3
      pos 7269
      pos 7498
      pos 15450
  term isissysstatauthfails
    doc 0
      freq 3
      pos 7263
      pos 7408
      pos 15457
  term isissysstatauthtypefails
    doc 0
      freq 3
      pos 7261
      pos 7375
      pos 15456
  term isissysstatcorrlsps
    doc 0
      freq 3
      pos 7259
      pos 7303
      pos 15447
  term isissysstatidfieldlenmismatches
    doc 0
      freq 3
      pos 7275
      pos 7604
      pos 15453
  term isissysstatlevel
    doc 0
      freq 3
      pos 7240
      pos 7257
      pos 7283
  term isissysstatlspdbaseoloads
    doc 0
      freq 4
      pos 7265
      pos 7441
      pos 12823
      pos 15448
  term isissysstatlsperrors
    doc 0
      freq 5
      pos 7281
      pos 7368
      pos 7702
      pos 14357
      pos 15458
  term isissysstatmanaddrdropfromareas
    doc 0
      freq 4
      pos 7267
      pos 7468
      pos 12875
      pos 15449
  term isissysstatownlsppurges
    doc 0
      freq 3
      pos 7273
      pos 7568
      pos 15452
  term isissysstatpartchanges
    doc 0
      freq 3
      pos 7277
      pos 7651
      pos 15454
  term isissysstatseqnumskips
    doc 0
      freq 3
      pos 7271
      pos 7541
      pos 15451
  term isissysstatspfruns
    doc 0
      freq 3
      pos 7279
      pos 7667
      pos 15455
  term isissystem
    doc 0
      freq 8
      pos 462
      pos 1277
      pos 2280
      pos 3130
      pos 3402
      pos 3585
      pos 4093
      pos 4473
  term isissystemcounter
    doc 0
      freq 1
      pos 668
  term isissystemcounterentry
    doc 0
      freq 17
      pos 7205
      pos 7222
      pos 7226
      pos 7243
      pos 7301
      pos 7373
      pos 7406
      pos 7439
      pos 7466
      pos 7496
      pos 7539
      pos 7566
      pos 7602
      pos 7649
      pos 7665
      pos 7700
      pos 7732
  term isissystemcountertabl
    doc 0
      freq 3
      pos 7192
      pos 7199
      pos 7241
  term isissystemgroup
    doc 0
      freq 4
      pos 14535
      pos 14749
      pos 14819
      pos 15402
  term isissystemid
    doc 0
      freq 6
      pos 1432
      pos 2386
      pos 4515
      pos 4526
      pos 8897
      pos 9121
  term isissystp
    doc 0
      freq 1
      pos 5869
  term isissysversion
    doc 0
      freq 2
      pos 2282
      pos 15406
  term isissyswaittim
    doc 0
      freq 4
      pos 2658
      pos 14883
      pos 15412
      pos 16514
  term isisunsigned16tc
    doc 0
      freq 21
      pos 2020
      pos 2610
      pos 2662
      pos 2805
      pos 2853
      pos 4719
      pos 4809
      pos 6371
      pos 6978
      pos 8903
      pos 9235
      pos 11789
      pos 11791
      pos 11793
      pos 11899
      pos 11921
      pos 11945
      pos 12113
      pos 12196
      pos 12530
      pos 12574
  term isisunsigned8tc
    doc 0
      freq 10
      pos 2055
      pos 11795
      pos 11964
      pos 12115
      pos 12117
      pos 12218
      pos 12237
      pos 12413
      pos 12438
      pos 12476
  term isisversionskew
    doc 0
      freq 3
      pos 13589
      pos 13647
      pos 15646
  term isiswidemetric
    doc 0
      freq 3
      pos 1745
      pos 6355
      pos 6443
  term isl.rdc.toshiba.co.jp
    doc 12
      freq 1
      pos 7645
  term isn't
    doc 11
      freq 2
      pos 1916
      pos 1960
  term iso
    doc 0
      freq 18
      pos 322
      pos 358
      pos 366
      pos 1138
      pos 1574
      pos 1683
      pos 1718
      pos 1739
      pos 1759
      pos 1844
      pos 1899
      pos 1939
      pos 1985
      pos 2014
      pos 16886
      pos 16911
      pos 16913
      pos 16918
    doc 2
      freq 2
      pos 2522
      pos 2578
    doc 3
      freq 1
      pos 4404
    doc 6
      freq 1
      pos 2987
    doc 17
      freq 9
      pos 493
      pos 526
      pos 863
      pos 888
      pos 2007
      pos 2095
      pos 2170
      pos 2210
      pos 2235
  term iso10589
    doc 0
      freq 3
      pos 324
      pos 10459
      pos 16885
  term iso10733
    doc 0
      freq 2
      pos 368
      pos 16917
  term iso8473
    doc 0
      freq 4
      pos 1673
      pos 1694
      pos 2945
      pos 10352
  term iso9834
    doc 17
      freq 2
      pos 594
      pos 1999
  term isolated
    doc 1
      freq 1
      pos 8078
    doc 6
      freq 1
      pos 2743
    doc 12
      freq 2
      pos 2615
      pos 3367
  term isp
    doc 12
      freq 1
      pos 5322
  term isps
    doc 13
      freq 1
      pos 2618
  term israel
    doc 3
      freq 1
      pos 4925
  term iss
    doc 0
      freq 1
      pos 7871
  term issuanc
    doc 17
      freq 1
      pos 335
  term issue
    doc 1
      freq 2
      pos 4282
      pos 7658
    doc 2
      freq 1
      pos 770
    doc 3
      freq 2
      pos 1743
      pos 5405
    doc 7
      freq 1
      pos 1486
    doc 9
      freq 1
      pos 1632
    doc 10
      freq 1
      pos 10891
    doc 12
      freq 4
      pos 6680
      pos 8499
      pos 8840
      pos 9098
    doc 13
      freq 1
      pos 2585
    doc 15
      freq 9
      pos 464
      pos 1201
      pos 2024
      pos 2160
      pos 2803
      pos 3040
      pos 3490
      pos 3494
      pos 3540
    doc 17
      freq 4
      pos 1324
      pos 1520
      pos 1730
      pos 1871
    skipList 
      level 0
        skipDoc 13
        skipDocFP 1273595
        impacts 
          impact 
            freq 1
            norm 95
          impact 
            freq 2
            norm 107
          impact 
            freq 4
            norm 113
        impactsEnd 
  term issued
    doc 0
      freq 1
      pos 1546
    doc 7
      freq 1
      pos 529
    doc 10
      freq 1
      pos 6072
    doc 17
      freq 2
      pos 1343
      pos 1379
  term issuer
    doc 17
      freq 4
      pos 1719
      pos 1740
      pos 1867
      pos 1941
  term issuers
    doc 17
      freq 1
      pos 1550
  term issues
    doc 1
      freq 3
      pos 987
      pos 7732
      pos 8375
    doc 2
      freq 10
      pos 386
      pos 4747
      pos 4832
      pos 4861
      pos 4875
      pos 4901
      pos 5126
      pos 5232
      pos 5476
      pos 6278
    doc 3
      freq 1
      pos 370
    doc 5
      freq 1
      pos 958
    doc 6
      freq 2
      pos 456
      pos 2574
    doc 8
      freq 2
      pos 1708
      pos 1711
    doc 10
      freq 1
      pos 11029
    doc 12
      freq 12
      pos 24
      pos 71
      pos 122
      pos 515
      pos 557
      pos 716
      pos 1719
      pos 2710
      pos 3653
      pos 3941
      pos 6791
      pos 7797
    doc 13
      freq 1
      pos 1558
    doc 15
      freq 34
      pos 35
      pos 131
      pos 178
      pos 197
      pos 213
      pos 238
      pos 252
      pos 308
      pos 449
      pos 495
      pos 508
      pos 638
      pos 816
      pos 822
      pos 856
      pos 1009
      pos 1028
      pos 1340
      pos 1396
      pos 1497
      pos 1662
      pos 1671
      pos 1756
      pos 2151
      pos 2597
      pos 3009
      pos 3059
      pos 3232
      pos 3410
      pos 3672
      pos 3733
      pos 3805
      pos 4011
      pos 4074
    doc 16
      freq 1
      pos 1626
    skipList 
      level 0
        skipDoc 12
        skipDocFP 1274850
        impacts 
          impact 
            freq 2
            norm 97
          impact 
            freq 10
            norm 108
          impact 
            freq 12
            norm 113
        impactsEnd 
  term issuing
    doc 10
      freq 1
      pos 11046
    doc 11
      freq 1
      pos 7993
    doc 17
      freq 1
      pos 165
  term istyp
    doc 0
      freq 1
      pos 2376
  term it
    doc 0
      freq 19
      pos 128
      pos 326
      pos 1141
      pos 2486
      pos 2993
      pos 3002
      pos 4999
      pos 5103
      pos 5266
      pos 5921
      pos 5974
      pos 6245
      pos 14127
      pos 16303
      pos 16716
      pos 16810
      pos 16821
      pos 17388
      pos 17391
    doc 1
      freq 60
      pos 139
      pos 442
      pos 797
      pos 915
      pos 923
      pos 1192
      pos 1302
      pos 1400
      pos 1416
      pos 1433
      pos 1482
      pos 1676
      pos 1717
      pos 2602
      pos 2801
      pos 3203
      pos 3235
      pos 3795
      pos 3836
      pos 3960
      pos 4136
      pos 4350
      pos 4490
      pos 4659
      pos 4706
      pos 4725
      pos 4744
      pos 4980
      pos 5427
      pos 5485
      pos 5602
      pos 5643
      pos 5834
      pos 5979
      pos 6478
      pos 6483
      pos 7010
      pos 7035
      pos 7061
      pos 7069
      pos 7140
      pos 7282
      pos 7380
      pos 7467
      pos 7521
      pos 7534
      pos 8088
      pos 8107
      pos 8316
      pos 8323
      pos 8445
      pos 8526
      pos 8554
      pos 8646
      pos 8714
      pos 8733
      pos 8759
      pos 8832
      pos 9769
      pos 9772
    doc 2
      freq 24
      pos 34
      pos 922
      pos 949
      pos 1027
      pos 1056
      pos 1133
      pos 1178
      pos 1229
      pos 1608
      pos 1962
      pos 2138
      pos 2169
      pos 4382
      pos 4386
      pos 4553
      pos 4790
      pos 5554
      pos 5649
      pos 5702
      pos 5912
      pos 5936
      pos 6067
      pos 6566
      pos 6569
    doc 3
      freq 28
      pos 143
      pos 425
      pos 1069
      pos 1198
      pos 1716
      pos 1758
      pos 1803
      pos 1948
      pos 2056
      pos 2297
      pos 2519
      pos 2627
      pos 2763
      pos 2847
      pos 3285
      pos 3347
      pos 3406
      pos 4281
      pos 5223
      pos 5250
      pos 5289
      pos 5326
      pos 5393
      pos 5403
      pos 5605
      pos 5823
      pos 6118
      pos 6121
    doc 4
      freq 26
      pos 335
      pos 653
      pos 850
      pos 1096
      pos 1225
      pos 1389
      pos 1426
      pos 1525
      pos 1606
      pos 1848
      pos 2212
      pos 2688
      pos 2873
      pos 2930
      pos 3099
      pos 3137
      pos 3398
      pos 3404
      pos 4195
      pos 4577
      pos 4594
      pos 5557
      pos 5925
      pos 6001
      pos 6273
      pos 6276
    doc 5
      freq 16
      pos 367
      pos 485
      pos 547
      pos 968
      pos 1134
      pos 2071
      pos 2301
      pos 2450
      pos 2482
      pos 3026
      pos 3113
      pos 3524
      pos 3604
      pos 3619
      pos 4603
      pos 4606
    doc 6
      freq 10
      pos 37
      pos 224
      pos 827
      pos 955
      pos 1002
      pos 1342
      pos 1553
      pos 2085
      pos 3403
      pos 3406
    doc 7
      freq 6
      pos 48
      pos 165
      pos 1281
      pos 1600
      pos 3108
      pos 3111
    doc 8
      freq 2
      pos 2325
      pos 2328
    doc 9
      freq 5
      pos 925
      pos 975
      pos 1536
      pos 1970
      pos 1973
    doc 10
      freq 118
      pos 133
      pos 584
      pos 802
      pos 911
      pos 1150
      pos 1428
      pos 1509
      pos 1628
      pos 1762
      pos 1887
      pos 1904
      pos 2019
      pos 2026
      pos 2205
      pos 2402
      pos 2409
      pos 2432
      pos 2454
      pos 2478
      pos 2487
      pos 2584
      pos 3034
      pos 3063
      pos 3484
      pos 3513
      pos 3607
      pos 3641
      pos 3652
      pos 3684
      pos 3818
      pos 4077
      pos 4095
      pos 4107
      pos 4124
      pos 4279
      pos 4325
      pos 4337
      pos 4377
      pos 4390
      pos 4420
      pos 4436
      pos 4438
      pos 4446
      pos 4466
      pos 4730
      pos 4737
      pos 5411
      pos 5865
      pos 5918
      pos 6091
      pos 6412
      pos 6447
      pos 6582
      pos 7016
      pos 7051
      pos 7101
      pos 7298
      pos 7480
      pos 7513
      pos 7592
      pos 7662
      pos 7722
      pos 7860
      pos 7896
      pos 8078
      pos 8412
      pos 8441
      pos 8612
      pos 8635
      pos 8810
      pos 8819
      pos 8924
      pos 8951
      pos 8977
      pos 9008
      pos 9031
      pos 9038
      pos 9182
      pos 9186
      pos 9189
      pos 9295
      pos 9333
      pos 9354
      pos 9368
      pos 9447
      pos 9604
      pos 9687
      pos 10085
      pos 10104
      pos 10204
      pos 10255
      pos 10313
      pos 10379
      pos 10414
      pos 10424
      pos 10514
      pos 10713
      pos 10908
      pos 10919
      pos 10956
      pos 11057
      pos 11111
      pos 11145
      pos 11190
      pos 11213
      pos 11241
      pos 11283
      pos 11365
      pos 11569
      pos 11657
      pos 11751
      pos 11864
      pos 12212
      pos 12274
      pos 13027
      pos 13043
      pos 13631
      pos 13634
    doc 11
      freq 75
      pos 50
      pos 167
      pos 644
      pos 680
      pos 692
      pos 1297
      pos 1411
      pos 1414
      pos 1636
      pos 1778
      pos 1917
      pos 1919
      pos 1927
      pos 1961
      pos 2408
      pos 2424
      pos 2450
      pos 2526
      pos 3594
      pos 4106
      pos 4122
      pos 5016
      pos 5132
      pos 5138
      pos 5261
      pos 5298
      pos 5307
      pos 5568
      pos 5584
      pos 5602
      pos 5613
      pos 5734
      pos 5750
      pos 5768
      pos 5779
      pos 5859
      pos 5883
      pos 6041
      pos 6054
      pos 6091
      pos 6099
      pos 6110
      pos 6119
      pos 6296
      pos 6320
      pos 6409
      pos 6518
      pos 6543
      pos 6556
      pos 6565
      pos 6959
      pos 7042
      pos 7086
      pos 7195
      pos 7311
      pos 7464
      pos 7469
      pos 7500
      pos 7801
      pos 7812
      pos 7820
      pos 7823
      pos 7835
      pos 7920
      pos 7928
      pos 7934
      pos 7938
      pos 8000
      pos 8406
      pos 8417
      pos 8427
      pos 9036
      pos 9387
      pos 10792
      pos 10795
    doc 12
      freq 62
      pos 40
      pos 519
      pos 566
      pos 618
      pos 1159
      pos 1374
      pos 1568
      pos 1981
      pos 1995
      pos 2028
      pos 2048
      pos 2063
      pos 2378
      pos 2382
      pos 2474
      pos 2621
      pos 2633
      pos 2911
      pos 2915
      pos 2962
      pos 3278
      pos 3304
      pos 3419
      pos 3676
      pos 3763
      pos 3939
      pos 4089
      pos 4235
      pos 4297
      pos 4335
      pos 4425
      pos 4439
      pos 4572
      pos 4597
      pos 4626
      pos 4841
      pos 4881
      pos 5104
      pos 5150
      pos 5175
      pos 5180
      pos 5196
      pos 5222
      pos 5684
      pos 5689
      pos 5714
      pos 6053
      pos 6356
      pos 6613
      pos 6855
      pos 6900
      pos 7979
      pos 8456
      pos 8712
      pos 8792
      pos 8919
      pos 8933
      pos 9153
      pos 9253
      pos 9274
      pos 9642
      pos 9645
    doc 13
      freq 52
      pos 49
      pos 682
      pos 1385
      pos 1531
      pos 1727
      pos 1741
      pos 1768
      pos 1782
      pos 1795
      pos 1803
      pos 1853
      pos 1912
      pos 1930
      pos 1985
      pos 2287
      pos 2394
      pos 2689
      pos 3740
      pos 3916
      pos 4486
      pos 4498
      pos 4562
      pos 4664
      pos 5285
      pos 5290
      pos 5525
      pos 5556
      pos 5815
      pos 5832
      pos 5858
      pos 5872
      pos 5898
      pos 5924
      pos 5966
      pos 5981
      pos 6059
      pos 6081
      pos 6110
      pos 6201
      pos 6215
      pos 6236
      pos 6255
      pos 6268
      pos 6298
      pos 6321
      pos 6343
      pos 6417
      pos 6440
      pos 6572
      pos 6682
      pos 7257
      pos 7260
    doc 14
      freq 13
      pos 37
      pos 1177
      pos 1252
      pos 1293
      pos 1359
      pos 1800
      pos 1847
      pos 2090
      pos 2298
      pos 2332
      pos 2655
      pos 5723
      pos 5726
    doc 15
      freq 29
      pos 48
      pos 704
      pos 763
      pos 790
      pos 835
      pos 1072
      pos 1255
      pos 1288
      pos 1372
      pos 1468
      pos 1474
      pos 1618
      pos 2215
      pos 2389
      pos 2695
      pos 2748
      pos 2904
      pos 3069
      pos 3086
      pos 3133
      pos 3171
      pos 3332
      pos 3437
      pos 3506
      pos 3652
      pos 3734
      pos 3823
      pos 4242
      pos 4245
    doc 16
      freq 10
      pos 157
      pos 1112
      pos 1138
      pos 1191
      pos 1234
      pos 1365
      pos 1764
      pos 1770
      pos 2853
      pos 2856
    doc 17
      freq 16
      pos 201
      pos 329
      pos 340
      pos 387
      pos 655
      pos 670
      pos 746
      pos 1097
      pos 1131
      pos 1174
      pos 1333
      pos 1387
      pos 1832
      pos 1908
      pos 2577
      pos 2580
    doc 18
      freq 8
      pos 258
      pos 562
      pos 1223
      pos 1599
      pos 1750
      pos 1917
      pos 2365
      pos 2368
    skipList 
      level 0
        skipDoc 7
        skipDocFP 1276581
        impacts 
          impact 
            freq 6
            norm 100
          impact 
            freq 10
            norm 101
          impact 
            freq 16
            norm 104
          impact 
            freq 28
            norm 107
          impact 
            freq 60
            norm 113
        impactsEnd 
        skipDoc 15
        skipDocFP 1279586
        impacts 
          impact 
            freq 5
            norm 95
          impact 
            freq 29
            norm 104
          impact 
            freq 52
            norm 109
          impact 
            freq 62
            norm 113
          impact 
            freq 75
            norm 114
          impact 
            freq 118
            norm 116
        impactsEnd 
  term it's
    doc 12
      freq 3
      pos 2413
      pos 2719
      pos 8190
    doc 15
      freq 2
      pos 2373
      pos 2980
  term it4ynm9t1905eiq9zphsr
    doc 10
      freq 1
      pos 6846
  term item
    doc 2
      freq 3
      pos 1150
      pos 3981
      pos 4768
    doc 5
      freq 2
      pos 2014
      pos 2024
    doc 13
      freq 3
      pos 4226
      pos 4231
      pos 4260
  term items
    doc 0
      freq 1
      pos 424
    doc 2
      freq 3
      pos 1211
      pos 3925
      pos 4753
    doc 5
      freq 1
      pos 1983
    doc 10
      freq 1
      pos 5069
    doc 13
      freq 2
      pos 3496
      pos 3738
  term iterations
    doc 2
      freq 1
      pos 3936
  term itojun
    doc 4
      freq 1
      pos 5492
  term its
    doc 0
      freq 6
      pos 2747
      pos 5543
      pos 9469
      pos 9652
      pos 9878
      pos 17491
    doc 1
      freq 12
      pos 1257
      pos 1846
      pos 3035
      pos 3882
      pos 4533
      pos 4953
      pos 8142
      pos 8486
      pos 8573
      pos 8725
      pos 8843
      pos 9872
    doc 2
      freq 6
      pos 2013
      pos 3941
      pos 4644
      pos 6095
      pos 6303
      pos 6669
    doc 3
      freq 5
      pos 1377
      pos 1591
      pos 2730
      pos 5385
      pos 6221
    doc 4
      freq 5
      pos 636
      pos 976
      pos 1387
      pos 2256
      pos 6376
    doc 5
      freq 4
      pos 1347
      pos 3799
      pos 4015
      pos 4706
    doc 6
      freq 7
      pos 91
      pos 152
      pos 163
      pos 1480
      pos 1562
      pos 2190
      pos 3506
    doc 7
      freq 1
      pos 3211
    doc 8
      freq 2
      pos 1703
      pos 2428
    doc 9
      freq 4
      pos 257
      pos 1160
      pos 1334
      pos 2073
    doc 10
      freq 20
      pos 962
      pos 1320
      pos 1962
      pos 2012
      pos 2688
      pos 3279
      pos 3348
      pos 4453
      pos 5898
      pos 6590
      pos 7306
      pos 7675
      pos 7947
      pos 8750
      pos 8864
      pos 9823
      pos 10506
      pos 11049
      pos 11054
      pos 13734
    doc 11
      freq 5
      pos 1844
      pos 2039
      pos 6081
      pos 6652
      pos 10895
    doc 12
      freq 5
      pos 2224
      pos 2959
      pos 4667
      pos 8684
      pos 9745
    doc 13
      freq 7
      pos 4236
      pos 4420
      pos 4576
      pos 4847
      pos 5427
      pos 5792
      pos 7360
    doc 14
      freq 1
      pos 5826
    doc 15
      freq 7
      pos 555
      pos 760
      pos 1006
      pos 1383
      pos 2852
      pos 3664
      pos 4345
    doc 16
      freq 2
      pos 377
      pos 2956
    doc 17
      freq 4
      pos 192
      pos 620
      pos 1189
      pos 2680
    doc 18
      freq 8
      pos 197
      pos 233
      pos 437
      pos 966
      pos 1199
      pos 1347
      pos 1665
      pos 2468
    skipList 
      level 0
        skipDoc 7
        skipDocFP 1287313
        impacts 
          impact 
            freq 1
            norm 100
          impact 
            freq 7
            norm 101
          impact 
            freq 12
            norm 113
        impactsEnd 
        skipDoc 15
        skipDocFP 1288183
        impacts 
          impact 
            freq 4
            norm 95
          impact 
            freq 7
            norm 104
          impact 
            freq 20
            norm 116
        impactsEnd 
  term itself
    doc 0
      freq 3
      pos 1229
      pos 12981
      pos 16761
    doc 1
      freq 5
      pos 928
      pos 2941
      pos 6115
      pos 8400
      pos 8538
    doc 3
      freq 3
      pos 845
      pos 2886
      pos 4102
    doc 4
      freq 1
      pos 5675
    doc 5
      freq 5
      pos 767
      pos 951
      pos 2800
      pos 2892
      pos 2953
    doc 8
      freq 1
      pos 1117
    doc 10
      freq 7
      pos 1360
      pos 1370
      pos 2648
      pos 9143
      pos 9417
      pos 10286
      pos 13061
    doc 11
      freq 1
      pos 728
    doc 12
      freq 2
      pos 2215
      pos 6853
    doc 13
      freq 2
      pos 1581
      pos 6053
    doc 15
      freq 1
      pos 2834
    skipList 
      level 0
        skipDoc 11
        skipDocFP 1289969
        impacts 
          impact 
            freq 1
            norm 97
          impact 
            freq 5
            norm 104
          impact 
            freq 7
            norm 116
        impactsEnd 
  term itu
    doc 1
      freq 1
      pos 9134
    doc 17
      freq 3
      pos 495
      pos 2001
      pos 2124
  term itug
    doc 1
      freq 2
      pos 601
      pos 9133
  term iuyd1y2yigak3ktdfnakw2xv7jkvyzcrl0vakdal3ol3z0t
    doc 10
      freq 1
      pos 12621
  term iv
    doc 1
      freq 1
      pos 6923
    doc 7
      freq 2
      pos 846
      pos 2256
  term iwhbqs0l8wgyy
    doc 11
      freq 1
      pos 9922
  term ixnzemotzbgzdarnmdbqxj4gtxsyvsa1xhnvstesqzfpqckid0etuj2bwv5yuz
    doc 10
      freq 1
      pos 12619
  term ixv0hsuv
    doc 11
      freq 1
      pos 10313
  term iz7gtkgaaaaaaaaaaaaaaaaaaaaaaaaaabapx4dy
    doc 10
      freq 1
      pos 12820
  term iz9ibl2eo6pu5
    doc 10
      freq 1
      pos 12775
  term j
    doc 0
      freq 7
      pos 3
      pos 17045
      pos 17066
      pos 17084
      pos 17116
      pos 17137
      pos 17174
    doc 2
      freq 10
      pos 2800
      pos 2958
      pos 3073
      pos 3168
      pos 3212
      pos 3229
      pos 3269
      pos 3271
      pos 3287
      pos 3329
    doc 3
      freq 1
      pos 4715
    doc 4
      freq 3
      pos 5215
      pos 5348
      pos 5352
    doc 5
      freq 4
      pos 4164
      pos 4190
      pos 4317
      pos 4325
    doc 6
      freq 4
      pos 3
      pos 13
      pos 1740
      pos 2953
    doc 9
      freq 3
      pos 1655
      pos 1689
      pos 1741
    doc 10
      freq 10
      pos 3
      pos 12671
      pos 13092
      pos 13100
      pos 13137
      pos 13153
      pos 13170
      pos 13290
      pos 13364
      pos 13388
    doc 11
      freq 8
      pos 21
      pos 1463
      pos 5142
      pos 5158
      pos 9631
      pos 9639
      pos 9657
      pos 10527
    doc 12
      freq 10
      pos 12
      pos 7019
      pos 7100
      pos 7175
      pos 7332
      pos 7353
      pos 7440
      pos 7591
      pos 7729
      pos 7795
    doc 13
      freq 8
      pos 15
      pos 19
      pos 6814
      pos 6830
      pos 6838
      pos 6860
      pos 6884
      pos 6886
    doc 14
      freq 2
      pos 5472
      pos 5494
    doc 15
      freq 1
      pos 3941
    doc 18
      freq 1
      pos 14
    skipList 
      level 0
        skipDoc 10
        skipDocFP 1291734
        impacts 
          impact 
            freq 3
            norm 95
          impact 
            freq 4
            norm 101
          impact 
            freq 10
            norm 108
        impactsEnd 
  term j2006
    doc 12
      freq 2
      pos 4076
      pos 7727
  term j6fyfk
    doc 11
      freq 1
      pos 10111
  term j7kxb7zkisvug9xu
    doc 10
      freq 1
      pos 6229
  term j9f
    doc 10
      freq 1
      pos 12730
  term ja4qfzmisjo3yid5d2vely
    doc 11
      freq 1
      pos 10060
  term jaap
    doc 18
      freq 1
      pos 2025
  term jacobson
    doc 5
      freq 1
      pos 4306
    doc 6
      freq 1
      pos 3071
    doc 13
      freq 1
      pos 6762
  term jakob
    doc 18
      freq 1
      pos 2027
  term jalbcnqn2fheeigk
    doc 10
      freq 1
      pos 6844
  term james
    doc 2
      freq 1
      pos 362
    doc 6
      freq 2
      pos 3180
      pos 3198
  term jamin
    doc 6
      freq 1
      pos 2880
  term jan
    doc 11
      freq 1
      pos 6187
  term janitorial
    doc 12
      freq 2
      pos 5673
      pos 6148
  term january
    doc 1
      freq 3
      pos 8927
      pos 8951
      pos 9179
    doc 2
      freq 4
      pos 378
      pos 2321
      pos 2574
      pos 3408
    doc 3
      freq 2
      pos 4399
      pos 4625
    doc 8
      freq 2
      pos 1760
      pos 2076
    doc 11
      freq 1
      pos 9693
    doc 12
      freq 3
      pos 7139
      pos 7740
      pos 7786
  term japan
    doc 13
      freq 1
      pos 7003
  term jari
    doc 9
      freq 1
      pos 1636
  term jaures
    doc 17
      freq 1
      pos 2389
  term javd5
    doc 10
      freq 1
      pos 12637
  term jayakumar
    doc 1
      freq 2
      pos 9200
      pos 9201
  term jb21g6
    doc 10
      freq 1
      pos 6256
  term jcbe9b
    doc 11
      freq 1
      pos 9984
  term jcnchf
    doc 10
      freq 1
      pos 6258
  term jdrosen
    doc 11
      freq 1
      pos 10580
  term je7c596xgndczdv4ujgrihpe1pfy
    doc 11
      freq 1
      pos 10407
  term jean
    doc 11
      freq 1
      pos 9561
    doc 13
      freq 1
      pos 6964
    doc 17
      freq 1
      pos 2388
  term jeff
    doc 0
      freq 4
      pos 1105
      pos 15931
      pos 15956
      pos 17197
  term jeffp
    doc 0
      freq 2
      pos 1116
      pos 17209
  term jeffre
    doc 2
      freq 2
      pos 3466
      pos 4477
  term jefsey
    doc 12
      freq 1
      pos 6800
  term jennings
    doc 10
      freq 44
      pos 14
      pos 167
      pos 391
      pos 782
      pos 1245
      pos 1696
      pos 2083
      pos 2509
      pos 2964
      pos 3368
      pos 3780
      pos 4179
      pos 4590
      pos 4934
      pos 5394
      pos 5759
      pos 6049
      pos 6267
      pos 6520
      pos 6775
      pos 6961
      pos 7265
      pos 7595
      pos 8027
      pos 8461
      pos 8981
      pos 9471
      pos 9936
      pos 10326
      pos 10782
      pos 11199
      pos 11537
      pos 11832
      pos 12089
      pos 12380
      pos 12527
      pos 12691
      pos 12826
      pos 13076
      pos 13287
      pos 13326
      pos 13430
      pos 13455
      pos 13786
    doc 11
      freq 3
      pos 9474
      pos 9499
      pos 9697
  term jeong
    doc 12
      freq 2
      pos 7439
      pos 7728
  term jesse
    doc 6
      freq 1
      pos 3098
  term jftf
    doc 11
      freq 1
      pos 10315
  term jhk
    doc 10
      freq 1
      pos 6853
  term jhz0
    doc 10
      freq 1
      pos 12812
  term jiclark
    doc 6
      freq 1
      pos 3216
  term jim
    doc 0
      freq 1
      pos 15933
    doc 4
      freq 1
      pos 5474
    doc 10
      freq 1
      pos 12134
  term jim.welch
    doc 6
      freq 1
      pos 3196
  term jinme
    doc 4
      freq 1
      pos 5495
    doc 12
      freq 4
      pos 6806
      pos 7373
      pos 7626
      pos 7644
  term jitter
    doc 6
      freq 14
      pos 230
      pos 387
      pos 661
      pos 755
      pos 777
      pos 908
      pos 931
      pos 967
      pos 983
      pos 1513
      pos 1542
      pos 1622
      pos 2208
      pos 2375
  term jjayakum
    doc 1
      freq 1
      pos 9215
  term jk29
    doc 11
      freq 1
      pos 10314
  term jkf3w1o9vh9wxmqb54i57kb1k2txdotprnr1p31upln
    doc 11
      freq 1
      pos 10340
  term jkx6fzrtbwv9ffmyhwcu
    doc 11
      freq 1
      pos 10205
  term jkyxaxmmzgsi7h9n3rvhingrioauizcph4
    doc 10
      freq 1
      pos 12485
  term jl
    doc 10
      freq 1
      pos 6893
  term jl78tej64g
    doc 11
      freq 1
      pos 9906
  term jlrbdrufwywgo13
    doc 11
      freq 1
      pos 9930
  term jntpu0hf7uhu
    doc 11
      freq 1
      pos 10129
  term jo
    doc 13
      freq 1
      pos 7055
  term joan
    doc 0
      freq 1
      pos 15917
  term joao
    doc 18
      freq 1
      pos 2032
  term joe
    doc 11
      freq 2
      pos 4299
      pos 9570
  term joerg
    doc 13
      freq 1
      pos 7039
  term johan
    doc 12
      freq 2
      pos 9441
      pos 9452
    doc 18
      freq 2
      pos 2174
      pos 2186
  term john
    doc 1
      freq 1
      pos 9266
    doc 6
      freq 3
      pos 3003
      pos 3107
      pos 3144
    doc 7
      freq 1
      pos 1791
    doc 10
      freq 1
      pos 12129
    doc 11
      freq 2
      pos 9574
      pos 9605
  term john.shirron
    doc 1
      freq 1
      pos 9280
  term johnson
    doc 9
      freq 1
      pos 1650
  term johnston
    doc 5
      freq 1
      pos 4322
    doc 10
      freq 3
      pos 12122
      pos 13097
      pos 13385
    doc 11
      freq 3
      pos 19
      pos 9636
      pos 10555
    doc 13
      freq 1
      pos 6835
  term join
    doc 13
      freq 1
      pos 684
  term joined
    doc 13
      freq 1
      pos 4560
  term joining
    doc 2
      freq 1
      pos 934
  term joint
    doc 2
      freq 4
      pos 2088
      pos 5011
      pos 5619
      pos 5664
  term jon
    doc 0
      freq 1
      pos 15935
    doc 10
      freq 2
      pos 9648
      pos 13405
    doc 11
      freq 1
      pos 9481
  term jon.peterson
    doc 10
      freq 1
      pos 13424
  term jonathan
    doc 2
      freq 1
      pos 6370
    doc 10
      freq 2
      pos 12115
      pos 12139
    doc 11
      freq 1
      pos 10564
  term jonnal
    doc 0
      freq 1
      pos 15922
  term jose
    doc 1
      freq 4
      pos 9211
      pos 9244
      pos 9291
      pos 9305
    doc 3
      freq 1
      pos 4760
    doc 4
      freq 1
      pos 6068
    doc 10
      freq 1
      pos 13442
  term josefsson
    doc 10
      freq 1
      pos 13213
  term jp6dsqn8j6s1tcchaebuxjtipsq5khwlcpqhncg
    doc 11
      freq 1
      pos 9947
  term jqd
    doc 10
      freq 1
      pos 12793
  term jtb
    doc 10
      freq 1
      pos 12634
  term jth
    doc 6
      freq 1
      pos 1760
  term ju36doy7yl79aisoddj7iq1zuvavmmldn
    doc 11
      freq 1
      pos 10078
  term judgment
    doc 7
      freq 1
      pos 1217
  term juergen
    doc 0
      freq 1
      pos 15964
  term juha
    doc 13
      freq 2
      pos 7022
      pos 7036
  term july
    doc 2
      freq 6
      pos 834
      pos 2440
      pos 2691
      pos 2914
      pos 3133
      pos 5195
    doc 6
      freq 1
      pos 3084
    doc 10
      freq 1
      pos 13224
    doc 11
      freq 1
      pos 9712
    doc 12
      freq 4
      pos 7047
      pos 7070
      pos 7194
      pos 7808
    doc 14
      freq 1
      pos 5403
    doc 15
      freq 1
      pos 3960
  term jun
    doc 4
      freq 1
      pos 5490
  term june
    doc 0
      freq 1
      pos 16992
    doc 2
      freq 10
      pos 2279
      pos 2424
      pos 2497
      pos 3035
      pos 3044
      pos 3063
      pos 3087
      pos 3101
      pos 3281
      pos 3325
    doc 5
      freq 2
      pos 4208
      pos 4339
    doc 6
      freq 1
      pos 2984
    doc 9
      freq 10
      pos 15
      pos 237
      pos 600
      pos 941
      pos 1377
      pos 1663
      pos 1701
      pos 1718
      pos 1732
      pos 1803
    doc 10
      freq 2
      pos 13114
      pos 13166
    doc 11
      freq 2
      pos 9653
      pos 9672
    doc 13
      freq 3
      pos 6852
      pos 6904
      pos 6918
    doc 15
      freq 1
      pos 3935
    skipList 
      level 0
        skipDoc 13
        skipDocFP 1300767
        impacts 
          impact 
            freq 10
            norm 95
        impactsEnd 
  term juniper
    doc 1
      freq 1
      pos 9368
    doc 3
      freq 1
      pos 4858
  term juniper.net
    doc 1
      freq 1
      pos 9379
    doc 3
      freq 1
      pos 4869
  term jusda
    doc 11
      freq 1
      pos 9965
  term just
    doc 1
      freq 2
      pos 7070
      pos 8856
    doc 2
      freq 1
      pos 4547
    doc 6
      freq 5
      pos 1087
      pos 1790
      pos 1805
      pos 1834
      pos 1857
    doc 10
      freq 3
      pos 606
      pos 971
      pos 9375
    doc 11
      freq 2
      pos 3261
      pos 7821
    doc 12
      freq 2
      pos 5198
      pos 8943
    doc 13
      freq 3
      pos 519
      pos 2755
      pos 6536
    doc 14
      freq 7
      pos 323
      pos 344
      pos 348
      pos 1969
      pos 1975
      pos 1991
      pos 1998
    doc 15
      freq 2
      pos 2506
      pos 2911
    doc 16
      freq 1
      pos 1172
    skipList 
      level 0
        skipDoc 14
        skipDocFP 1301876
        impacts 
          impact 
            freq 5
            norm 101
          impact 
            freq 7
            norm 107
        impactsEnd 
  term justifiabl
    doc 12
      freq 1
      pos 8971
  term justified
    doc 7
      freq 1
      pos 246
    doc 10
      freq 1
      pos 10977
    doc 12
      freq 1
      pos 5170
  term jvhjsupx6v5tt7hxuyddvyou7
    doc 11
      freq 1
      pos 10234
  term jx
    doc 10
      freq 1
      pos 12712
  term jx1epln3hwl
    doc 10
      freq 1
      pos 6864
  term jz0f84mgbew8
    doc 11
      freq 1
      pos 10113
  term jznbfx4itpu2q01iifukogmxw5tkcmocumyhmtaqtzxn6vlrgu24ghgwhp7
    doc 11
      freq 1
      pos 10364
  term k
    doc 0
      freq 5
      pos 16982
      pos 16998
      pos 17041
      pos 17062
      pos 17080
    doc 2
      freq 6
      pos 2465
      pos 2904
      pos 2919
      pos 2925
      pos 2995
      pos 3371
    doc 4
      freq 1
      pos 5426
    doc 5
      freq 2
      pos 4172
      pos 4363
    doc 6
      freq 2
      pos 1875
      pos 1883
    doc 10
      freq 1
      pos 12551
    doc 11
      freq 3
      pos 9700
      pos 10173
      pos 10337
    doc 12
      freq 2
      pos 7145
      pos 7348
    doc 13
      freq 1
      pos 6924
    skipList 
      level 0
        skipDoc 12
        skipDocFP 1303300
        impacts 
          impact 
            freq 2
            norm 101
          impact 
            freq 6
            norm 108
        impactsEnd 
  term k1ygmw
    doc 11
      freq 1
      pos 10066
  term k2h
    doc 3
      freq 1
      pos 4880
  term k4fnfeiqcjbcjfvpnuyr
    doc 10
      freq 1
      pos 12771
  term k6
    doc 11
      freq 1
      pos 10003
  term k6ni
    doc 11
      freq 1
      pos 10117
  term k7jytrl
    doc 11
      freq 1
      pos 10068
  term k9p
    doc 11
      freq 1
      pos 10100
  term k9y
    doc 10
      freq 1
      pos 12565
  term kamikodanak
    doc 13
      freq 1
      pos 6997
  term kanbpodhm5t0dutt6yb2
    doc 11
      freq 1
      pos 9959
  term kasenn
    doc 6
      freq 1
      pos 3153
  term kastenholz
    doc 0
      freq 1
      pos 16985
  term katz
    doc 0
      freq 2
      pos 17134
      pos 17148
  term kawa
    doc 1
      freq 1
      pos 9033
    doc 8
      freq 1
      pos 1909
  term kawasak
    doc 13
      freq 1
      pos 7000
  term kay
    doc 0
      freq 1
      pos 15950
  term kbm
    doc 9
      freq 19
      pos 130
      pos 236
      pos 563
      pos 599
      pos 675
      pos 693
      pos 775
      pos 823
      pos 897
      pos 919
      pos 940
      pos 957
      pos 1025
      pos 1311
      pos 1376
      pos 1440
      pos 1582
      pos 1731
      pos 1802
  term kbps
    doc 13
      freq 1
      pos 2443
  term kcn
    doc 9
      freq 9
      pos 470
      pos 719
      pos 758
      pos 805
      pos 1070
      pos 1155
      pos 1179
      pos 1416
      pos 1436
  term kdpxtomedcxaahfggise2wshcioifioqqc8gqahr
    doc 10
      freq 1
      pos 12456
  term kdr
    doc 10
      freq 1
      pos 6262
  term keep
    doc 9
      freq 2
      pos 900
      pos 1451
    doc 12
      freq 5
      pos 481
      pos 1116
      pos 1999
      pos 8648
      pos 8698
    doc 13
      freq 7
      pos 1748
      pos 2722
      pos 3685
      pos 4104
      pos 4773
      pos 6064
      pos 6086
  term keeping
    doc 10
      freq 1
      pos 7946
    doc 12
      freq 1
      pos 1162
  term keeps
    doc 0
      freq 4
      pos 4436
      pos 7193
      pos 7735
      pos 8250
  term keith
    doc 2
      freq 3
      pos 3569
      pos 3585
      pos 4280
  term kempf
    doc 2
      freq 1
      pos 363
  term ken
    doc 0
      freq 1
      pos 15915
    doc 6
      freq 1
      pos 3118
  term kensington
    doc 11
      freq 1
      pos 10541
  term kent
    doc 4
      freq 4
      pos 5367
      pos 5384
      pos 5410
      pos 5423
  term kept
    doc 0
      freq 1
      pos 12819
    doc 3
      freq 1
      pos 3882
    doc 12
      freq 1
      pos 4817
    doc 13
      freq 1
      pos 4142
    doc 15
      freq 1
      pos 3098
  term kerberos
    doc 7
      freq 2
      pos 2413
      pos 2826
  term kernel
    doc 12
      freq 2
      pos 3299
      pos 3349
  term kev9obztiemsrv
    doc 11
      freq 1
      pos 10001
  term key
    doc 0
      freq 4
      pos 952
      pos 7419
      pos 7432
      pos 16944
    doc 1
      freq 3
      pos 1159
      pos 8626
      pos 8897
    doc 2
      freq 11
      pos 1389
      pos 1405
      pos 2146
      pos 2330
      pos 2378
      pos 2810
      pos 4965
      pos 5729
      pos 5768
      pos 5984
      pos 6150
    doc 3
      freq 2
      pos 1234
      pos 4495
    doc 4
      freq 2
      pos 443
      pos 5270
    doc 5
      freq 50
      pos 225
      pos 289
      pos 420
      pos 589
      pos 603
      pos 772
      pos 776
      pos 779
      pos 801
      pos 809
      pos 823
      pos 849
      pos 912
      pos 1047
      pos 1289
      pos 1324
      pos 1348
      pos 1386
      pos 1400
      pos 1406
      pos 1419
      pos 1442
      pos 1458
      pos 1538
      pos 1957
      pos 1963
      pos 2032
      pos 2160
      pos 2188
      pos 2226
      pos 2560
      pos 2700
      pos 2705
      pos 2709
      pos 3062
      pos 3126
      pos 3272
      pos 3320
      pos 3394
      pos 3514
      pos 3534
      pos 3541
      pos 3641
      pos 3648
      pos 3652
      pos 3669
      pos 3872
      pos 3876
      pos 4125
      pos 4384
    doc 7
      freq 4
      pos 821
      pos 847
      pos 2231
      pos 2257
    doc 8
      freq 2
      pos 307
      pos 1765
    doc 9
      freq 12
      pos 26
      pos 104
      pos 129
      pos 674
      pos 692
      pos 718
      pos 774
      pos 956
      pos 1024
      pos 1586
      pos 1668
      pos 1712
    doc 10
      freq 28
      pos 675
      pos 1671
      pos 1960
      pos 2138
      pos 2704
      pos 2718
      pos 4301
      pos 5541
      pos 5645
      pos 5655
      pos 5702
      pos 6013
      pos 6193
      pos 6207
      pos 6245
      pos 6550
      pos 6821
      pos 6831
      pos 6876
      pos 7253
      pos 10695
      pos 10974
      pos 12302
      pos 12324
      pos 12333
      pos 13119
      pos 13240
      pos 13263
    doc 11
      freq 1
      pos 1596
    doc 12
      freq 1
      pos 5893
    doc 13
      freq 2
      pos 1183
      pos 6738
    doc 17
      freq 9
      pos 168
      pos 267
      pos 1499
      pos 1564
      pos 1573
      pos 1662
      pos 2030
      pos 2060
      pos 2138
    doc 18
      freq 1
      pos 2129
    skipList 
      level 0
        skipDoc 8
        skipDocFP 1306943
        impacts 
          impact 
            freq 2
            norm 97
          impact 
            freq 4
            norm 100
          impact 
            freq 50
            norm 104
        impactsEnd 
  term keyed
    doc 5
      freq 2
      pos 1258
      pos 1353
    doc 7
      freq 2
      pos 1100
      pos 2722
  term keyfram
    doc 2
      freq 4
      pos 1393
      pos 2115
      pos 2160
      pos 2794
  term keygen
    doc 9
      freq 5
      pos 723
      pos 739
      pos 749
      pos 752
      pos 782
  term keying
    doc 5
      freq 7
      pos 201
      pos 594
      pos 999
      pos 1023
      pos 2818
      pos 2873
      pos 4177
    doc 10
      freq 2
      pos 1720
      pos 10554
    doc 12
      freq 3
      pos 4545
      pos 5158
      pos 7563
  term keys
    doc 1
      freq 2
      pos 8713
      pos 8730
    doc 5
      freq 7
      pos 682
      pos 1227
      pos 1243
      pos 1250
      pos 1281
      pos 2933
      pos 3103
    doc 9
      freq 4
      pos 1037
      pos 1088
      pos 1115
      pos 1352
    doc 10
      freq 2
      pos 1643
      pos 10735
    doc 12
      freq 1
      pos 6917
    doc 17
      freq 2
      pos 1412
      pos 1559
    doc 18
      freq 5
      pos 356
      pos 472
      pos 1667
      pos 1670
      pos 1732
  term keywords
    doc 9
      freq 1
      pos 345
    doc 18
      freq 2
      pos 381
      pos 383
  term kfxy6pv
    doc 10
      freq 1
      pos 12749
  term kgg017n1jwvuluck3sqh21abajdbf6igo2d36mq6vqibmjgcvw2ghw
    doc 11
      freq 1
      pos 10494
  term khandekar
    doc 3
      freq 1
      pos 4974
  term kind
    doc 2
      freq 1
      pos 43
    doc 6
      freq 1
      pos 46
    doc 7
      freq 1
      pos 57
    doc 11
      freq 3
      pos 59
      pos 6525
      pos 7339
    doc 12
      freq 2
      pos 49
      pos 5878
    doc 13
      freq 1
      pos 58
    doc 14
      freq 1
      pos 46
    doc 15
      freq 2
      pos 57
      pos 2381
    skipList 
      level 0
        skipDoc 15
        skipDocFP 1310976
        impacts 
          impact 
            freq 1
            norm 100
          impact 
            freq 2
            norm 104
          impact 
            freq 3
            norm 114
        impactsEnd 
  term kinds
    doc 1
      freq 1
      pos 2238
    doc 12
      freq 2
      pos 1263
      pos 8122
    doc 13
      freq 5
      pos 490
      pos 1055
      pos 3637
      pos 5212
      pos 5244
  term kingdom
    doc 15
      freq 1
      pos 4032
  term kireet
    doc 1
      freq 2
      pos 9366
      pos 9378
    doc 3
      freq 2
      pos 4856
      pos 4868
  term kjivfjj5bd30xtv
    doc 11
      freq 1
      pos 10275
  term klensin
    doc 7
      freq 1
      pos 1792
    doc 12
      freq 1
      pos 7099
  term kmgu4sh5a4dn8ncccmlyp6amwcv
    doc 10
      freq 1
      pos 12759
  term know
    doc 1
      freq 1
      pos 4331
    doc 5
      freq 1
      pos 3347
    doc 10
      freq 2
      pos 6721
      pos 11214
    doc 11
      freq 2
      pos 1402
      pos 8360
    doc 12
      freq 4
      pos 2222
      pos 3291
      pos 3697
      pos 5680
    doc 13
      freq 1
      pos 4790
    doc 15
      freq 4
      pos 904
      pos 1244
      pos 2847
      pos 2969
  term knowing
    doc 6
      freq 1
      pos 2189
    doc 15
      freq 1
      pos 1159
  term knowledg
    doc 0
      freq 1
      pos 12966
    doc 1
      freq 1
      pos 4366
    doc 3
      freq 1
      pos 4802
    doc 4
      freq 2
      pos 4720
      pos 4729
    doc 13
      freq 4
      pos 5417
      pos 5434
      pos 5441
      pos 5577
    doc 15
      freq 1
      pos 1325
  term known
    doc 0
      freq 2
      pos 1376
      pos 16652
    doc 1
      freq 2
      pos 8491
      pos 8806
    doc 3
      freq 1
      pos 2849
    doc 4
      freq 1
      pos 1808
    doc 6
      freq 1
      pos 2243
    doc 7
      freq 1
      pos 1309
    doc 10
      freq 5
      pos 4012
      pos 7586
      pos 7934
      pos 8112
      pos 9058
    doc 11
      freq 6
      pos 417
      pos 1322
      pos 3571
      pos 7413
      pos 8717
      pos 8808
    doc 12
      freq 1
      pos 87
    doc 13
      freq 4
      pos 1705
      pos 2245
      pos 3507
      pos 3530
    doc 15
      freq 1
      pos 2907
    doc 18
      freq 1
      pos 1673
    skipList 
      level 0
        skipDoc 11
        skipDocFP 1313035
        impacts 
          impact 
            freq 1
            norm 100
          impact 
            freq 2
            norm 113
          impact 
            freq 6
            norm 114
        impactsEnd 
  term koch
    doc 12
      freq 1
      pos 6805
    doc 14
      freq 1
      pos 5491
    doc 18
      freq 1
      pos 2018
  term koen
    doc 0
      freq 1
      pos 15966
  term koit
    doc 10
      freq 1
      pos 12596
  term kolkman
    doc 14
      freq 1
      pos 5346
    doc 18
      freq 1
      pos 2014
  term kompell
    doc 1
      freq 2
      pos 8881
      pos 9367
    doc 3
      freq 1
      pos 4857
  term koskelainen
    doc 13
      freq 1
      pos 6970
  term kpcjrf8i38quytvhdmreub1rqhdnx7lfygd
    doc 10
      freq 1
      pos 12540
  term kruxmi1xestiuqmbovd
    doc 10
      freq 1
      pos 12797
  term ksinant
    doc 12
      freq 1
      pos 7264
  term ksneriyiwidaqab
    doc 10
      freq 1
      pos 6840
  term kt1mx8s1ozccpnk6nk6rax8t2qazvpi6g2at
    doc 11
      freq 1
      pos 10451
  term ku
    doc 13
      freq 1
      pos 6999
  term kumar
    doc 11
      freq 2
      pos 9438
      pos 9478
  term kundan
    doc 11
      freq 1
      pos 9534
  term kurtis
    doc 2
      freq 1
      pos 6360
  term kutscher
    doc 13
      freq 2
      pos 6811
      pos 6968
  term kvhpkbfu
    doc 10
      freq 2
      pos 6563
      pos 6656
  term kwyxzfadftzyw1st4e7v7roo4rqw5cnx6ncxb
    doc 10
      freq 1
      pos 12496
  term kyzviat
    doc 10
      freq 1
      pos 12126
  term l1
    doc 0
      freq 18
      pos 525
      pos 564
      pos 1905
      pos 2789
      pos 3513
      pos 3994
      pos 4040
      pos 4061
      pos 4121
      pos 6867
      pos 7867
      pos 8476
      pos 8478
      pos 8538
      pos 8540
      pos 8595
      pos 8597
      pos 9215
    doc 11
      freq 1
      pos 9932
  term l1defaultmetric
    doc 0
      freq 1
      pos 6421
  term l1intermediatesystem
    doc 0
      freq 1
      pos 9090
  term l1l2
    doc 0
      freq 5
      pos 6876
      pos 6889
      pos 8480
      pos 8542
      pos 8599
  term l1l2intermediatesystem
    doc 0
      freq 1
      pos 9094
  term l1stat
    doc 0
      freq 1
      pos 4956
  term l2
    doc 0
      freq 12
      pos 562
      pos 1908
      pos 2786
      pos 3516
      pos 3992
      pos 4038
      pos 4118
      pos 7869
      pos 8484
      pos 8546
      pos 8603
      pos 9224
    doc 3
      freq 1
      pos 1008
  term l2designatedintermediatesystem
    doc 0
      freq 1
      pos 6772
  term l2intermediatesystem
    doc 0
      freq 1
      pos 9092
  term l2intermediatesystempriority
    doc 0
      freq 1
      pos 6491
  term l2tpv3
    doc 3
      freq 4
      pos 4713
      pos 4727
      pos 5557
      pos 5559
  term l2vpns
    doc 8
      freq 1
      pos 2093
  term l4d305m2izqeumcalyfusqqf6ykswhzmgwdu08
    doc 11
      freq 1
      pos 10011
  term l4xivww3pvtrtb0f53o84qlbcl16tbnsxhb33uwn26ocvojgnbjk1llypuakdtkf
    doc 10
      freq 1
      pos 12590
  term l6997ws
    doc 11
      freq 1
      pos 10291
  term l80216
    doc 2
      freq 2
      pos 2768
      pos 2791
  term l8e
    doc 11
      freq 1
      pos 10197
  term l8mhkbj2iwcpic5ob8scqxfwutvj47
    doc 10
      freq 1
      pos 12591
  term l9cvpec6ngtk8xyh2rptancqlxvrhayk72bzwbj3eba0mxrm5qtfqhyheqc
    doc 11
      freq 1
      pos 10374
  term label
    doc 1
      freq 138
      pos 41
      pos 179
      pos 225
      pos 296
      pos 346
      pos 355
      pos 359
      pos 735
      pos 854
      pos 1189
      pos 1265
      pos 1284
      pos 1455
      pos 1469
      pos 1472
      pos 1491
      pos 1502
      pos 1516
      pos 1519
      pos 1529
      pos 1533
      pos 1555
      pos 1572
      pos 1595
      pos 1627
      pos 1653
      pos 1746
      pos 1756
      pos 1767
      pos 1781
      pos 1792
      pos 1801
      pos 1816
      pos 1852
      pos 2011
      pos 2054
      pos 2088
      pos 2096
      pos 2116
      pos 2135
      pos 2240
      pos 2245
      pos 2261
      pos 2378
      pos 2712
      pos 4178
      pos 4377
      pos 4386
      pos 4419
      pos 4539
      pos 4557
      pos 4568
      pos 4581
      pos 4610
      pos 4646
      pos 4680
      pos 4702
      pos 4752
      pos 4763
      pos 4810
      pos 4817
      pos 4841
      pos 4870
      pos 4893
      pos 4925
      pos 4949
      pos 4959
      pos 4968
      pos 4985
      pos 5053
      pos 5647
      pos 5742
      pos 5745
      pos 5764
      pos 5773
      pos 5808
      pos 5887
      pos 5913
      pos 5952
      pos 6299
      pos 6318
      pos 6335
      pos 6499
      pos 6511
      pos 6531
      pos 6539
      pos 6555
      pos 6580
      pos 6595
      pos 6630
      pos 6647
      pos 6662
      pos 6693
      pos 6787
      pos 6800
      pos 6829
      pos 6837
      pos 6852
      pos 6869
      pos 6877
      pos 6891
      pos 6904
      pos 6925
      pos 6939
      pos 6962
      pos 6970
      pos 6985
      pos 7074
      pos 7092
      pos 7145
      pos 7185
      pos 7244
      pos 7325
      pos 7328
      pos 7334
      pos 7348
      pos 7392
      pos 7396
      pos 7423
      pos 7438
      pos 7470
      pos 7481
      pos 7538
      pos 7541
      pos 7619
      pos 7653
      pos 7670
      pos 7698
      pos 7709
      pos 7720
      pos 7725
      pos 7738
      pos 7876
      pos 7921
      pos 8158
      pos 8946
      pos 9417
      pos 9486
    doc 3
      freq 11
      pos 362
      pos 1558
      pos 2188
      pos 2250
      pos 2252
      pos 2263
      pos 3370
      pos 3823
      pos 3848
      pos 4376
      pos 4394
    doc 8
      freq 2
      pos 1804
      pos 2071
    doc 14
      freq 50
      pos 501
      pos 524
      pos 661
      pos 750
      pos 767
      pos 788
      pos 823
      pos 856
      pos 930
      pos 967
      pos 977
      pos 991
      pos 1015
      pos 1052
      pos 1071
      pos 1132
      pos 1141
      pos 1266
      pos 1307
      pos 1413
      pos 1419
      pos 1441
      pos 1458
      pos 1493
      pos 1531
      pos 1590
      pos 1596
      pos 1617
      pos 1629
      pos 1643
      pos 1667
      pos 1704
      pos 1723
      pos 1732
      pos 1736
      pos 2022
      pos 2242
      pos 2245
      pos 2372
      pos 2375
      pos 2386
      pos 2638
      pos 2669
      pos 3234
      pos 3278
      pos 4311
      pos 4441
      pos 4999
      pos 5016
      pos 5168
    doc 18
      freq 6
      pos 1284
      pos 1303
      pos 1307
      pos 1332
      pos 1337
      pos 1345
  term labelled
    doc 3
      freq 1
      pos 3376
  term labels
    doc 1
      freq 5
      pos 1759
      pos 1785
      pos 1883
      pos 7127
      pos 7390
    doc 3
      freq 1
      pos 2255
    doc 14
      freq 11
      pos 714
      pos 878
      pos 1239
      pos 1397
      pos 1574
      pos 2536
      pos 2588
      pos 2807
      pos 2855
      pos 4977
      pos 5150
    doc 18
      freq 1
      pos 1570
  term laboratories
    doc 6
      freq 1
      pos 3143
    doc 13
      freq 1
      pos 6992
  term laboratory
    doc 13
      freq 1
      pos 7046
  term labs
    doc 13
      freq 1
      pos 10
  term lack
    doc 2
      freq 2
      pos 4503
      pos 5134
    doc 4
      freq 1
      pos 2288
    doc 10
      freq 1
      pos 9609
    doc 13
      freq 2
      pos 1649
      pos 1867
    doc 15
      freq 1
      pos 3216
  term lacks
    doc 10
      freq 1
      pos 11580
  term lag
    doc 2
      freq 1
      pos 4420
    doc 5
      freq 1
      pos 1118
  term lakshminath
    doc 5
      freq 1
      pos 4090
  term lan
    doc 0
      freq 11
      pos 1486
      pos 1536
      pos 6094
      pos 6099
      pos 6482
      pos 6569
      pos 6733
      pos 9203
      pos 16238
      pos 16574
      pos 16598
    doc 2
      freq 6
      pos 2641
      pos 2668
      pos 2675
      pos 2879
      pos 3010
      pos 3404
    doc 3
      freq 2
      pos 655
      pos 684
  term lane
    doc 14
      freq 1
      pos 5513
  term langill
    doc 2
      freq 4
      pos 2899
      pos 2990
      pos 3472
      pos 3591
  term languag
    doc 1
      freq 1
      pos 6283
    doc 16
      freq 2
      pos 1998
      pos 2366
    doc 17
      freq 1
      pos 1186
  term languages
    doc 1
      freq 1
      pos 9174
    doc 8
      freq 1
      pos 1755
  term lanidex
    doc 11
      freq 1
      pos 10569
  term lanlevel1
    doc 0
      freq 1
      pos 7839
  term lanlevel2
    doc 0
      freq 1
      pos 7841
  term lanpriority
    doc 0
      freq 1
      pos 9313
  term lans
    doc 0
      freq 2
      pos 6595
      pos 6863
    doc 2
      freq 1
      pos 3299
    doc 3
      freq 2
      pos 706
      pos 2388
  term lapb
    doc 7
      freq 1
      pos 2137
  term laptops
    doc 10
      freq 1
      pos 1692
  term laquot
    doc 10
      freq 1
      pos 4828
  term large
    doc 1
      freq 1
      pos 1289
    doc 3
      freq 1
      pos 4189
    doc 4
      freq 3
      pos 1564
      pos 4449
      pos 4561
    doc 5
      freq 1
      pos 115
    doc 6
      freq 3
      pos 417
      pos 838
      pos 860
    doc 10
      freq 1
      pos 1684
    doc 11
      freq 2
      pos 1096
      pos 4981
    doc 13
      freq 9
      pos 678
      pos 1048
      pos 1332
      pos 2449
      pos 3397
      pos 3984
      pos 4056
      pos 4344
      pos 6391
    doc 16
      freq 2
      pos 354
      pos 456
    skipList 
      level 0
        skipDoc 13
        skipDocFP 1322783
        impacts 
          impact 
            freq 3
            norm 101
          impact 
            freq 9
            norm 109
        impactsEnd 
  term largely
    doc 2
      freq 2
      pos 5166
      pos 5613
    doc 13
      freq 1
      pos 437
  term larger
    doc 0
      freq 3
      pos 2913
      pos 13879
      pos 13968
    doc 2
      freq 1
      pos 4274
    doc 4
      freq 1
      pos 2880
    doc 11
      freq 4
      pos 257
      pos 4346
      pos 4360
      pos 6948
    doc 12
      freq 3
      pos 8336
      pos 8937
      pos 9334
  term largest
    doc 0
      freq 1
      pos 2868
    doc 3
      freq 1
      pos 4234
  term larson
    doc 12
      freq 1
      pos 7744
    doc 14
      freq 1
      pos 5433
    doc 18
      freq 4
      pos 2020
      pos 2064
      pos 2085
      pos 2108
  term last
    doc 0
      freq 3
      pos 1072
      pos 6156
      pos 9346
    doc 2
      freq 2
      pos 5523
      pos 5530
    doc 6
      freq 6
      pos 306
      pos 1842
      pos 1863
      pos 1945
      pos 1964
      pos 1986
    doc 7
      freq 3
      pos 1343
      pos 1488
      pos 1499
    doc 12
      freq 1
      pos 6822
    doc 13
      freq 1
      pos 2532
    doc 18
      freq 2
      pos 1298
      pos 1712
  term lastly
    doc 12
      freq 1
      pos 4762
  term late
    doc 2
      freq 6
      pos 61
      pos 207
      pos 1137
      pos 3516
      pos 4556
      pos 4840
    doc 7
      freq 1
      pos 1355
  term latency
    doc 6
      freq 3
      pos 1500
      pos 1631
      pos 2426
    doc 9
      freq 2
      pos 158
      pos 276
    doc 12
      freq 3
      pos 2741
      pos 3514
      pos 3720
  term later
    doc 0
      freq 1
      pos 2196
    doc 2
      freq 1
      pos 3568
    doc 3
      freq 2
      pos 1709
      pos 1857
    doc 5
      freq 3
      pos 3335
      pos 3438
      pos 3584
    doc 11
      freq 1
      pos 1807
    doc 13
      freq 1
      pos 3006
    doc 15
      freq 1
      pos 1013
  term latest
    doc 15
      freq 1
      pos 339
  term latter
    doc 10
      freq 3
      pos 743
      pos 2837
      pos 10518
    doc 12
      freq 1
      pos 2876
  term lau
    doc 3
      freq 1
      pos 4714
  term launch
    doc 5
      freq 1
      pos 3623
    doc 9
      freq 1
      pos 438
  term laur
    doc 14
      freq 25
      pos 10
      pos 211
      pos 554
      pos 838
      pos 1215
      pos 1544
      pos 1865
      pos 2155
      pos 2546
      pos 2900
      pos 3253
      pos 3537
      pos 3835
      pos 4131
      pos 4217
      pos 4282
      pos 4404
      pos 4498
      pos 4580
      pos 4958
      pos 5186
      pos 5452
      pos 5527
      pos 5545
      pos 5878
  term laura
    doc 0
      freq 1
      pos 15946
  term layer
    doc 0
      freq 1
      pos 16937
    doc 1
      freq 12
      pos 106
      pos 128
      pos 186
      pos 237
      pos 449
      pos 1133
      pos 1197
      pos 1477
      pos 1728
      pos 1983
      pos 7954
      pos 8056
    doc 2
      freq 4
      pos 1956
      pos 2612
      pos 2648
      pos 2682
    doc 3
      freq 11
      pos 789
      pos 1057
      pos 1219
      pos 2874
      pos 2899
      pos 3073
      pos 4269
      pos 4443
      pos 4487
      pos 4721
      pos 5211
    doc 4
      freq 30
      pos 494
      pos 1049
      pos 1396
      pos 1474
      pos 1487
      pos 1491
      pos 1516
      pos 1533
      pos 1549
      pos 1575
      pos 1735
      pos 1770
      pos 2241
      pos 2726
      pos 2740
      pos 2949
      pos 2953
      pos 2972
      pos 2986
      pos 3209
      pos 3222
      pos 3513
      pos 3525
      pos 3686
      pos 3700
      pos 3852
      pos 3963
      pos 4575
      pos 4586
      pos 4646
    doc 7
      freq 2
      pos 2117
      pos 2148
    doc 10
      freq 1
      pos 531
    doc 11
      freq 6
      pos 387
      pos 397
      pos 7003
      pos 7016
      pos 7150
      pos 7163
    doc 12
      freq 1
      pos 2237
    doc 13
      freq 2
      pos 1120
      pos 2330
    skipList 
      level 0
        skipDoc 11
        skipDocFP 1326215
        impacts 
          impact 
            freq 2
            norm 100
          impact 
            freq 11
            norm 107
          impact 
            freq 30
            norm 108
        impactsEnd 
  term layer2
    doc 8
      freq 1
      pos 693
  term layers
    doc 1
      freq 2
      pos 1102
      pos 1103
    doc 2
      freq 1
      pos 2734
    doc 4
      freq 3
      pos 4600
      pos 4633
      pos 5259
    doc 7
      freq 1
      pos 2054
    doc 13
      freq 1
      pos 943
  term layout
    doc 11
      freq 1
      pos 749
  term lb2005
    doc 12
      freq 2
      pos 1919
      pos 7743
  term lbiu
    doc 11
      freq 1
      pos 9899
  term lcp
    doc 7
      freq 1
      pos 2502
  term ldap
    doc 13
      freq 1
      pos 2819
  term ldh
    doc 14
      freq 5
      pos 2085
      pos 2106
      pos 2140
      pos 2213
      pos 2285
  term ldp
    doc 1
      freq 86
      pos 44
      pos 182
      pos 208
      pos 242
      pos 245
      pos 345
      pos 367
      pos 372
      pos 431
      pos 738
      pos 762
      pos 765
      pos 785
      pos 839
      pos 1068
      pos 1376
      pos 1820
      pos 1831
      pos 1841
      pos 1869
      pos 2051
      pos 2060
      pos 2072
      pos 2081
      pos 2087
      pos 2189
      pos 2229
      pos 2233
      pos 2267
      pos 2274
      pos 2287
      pos 2339
      pos 2425
      pos 2699
      pos 2799
      pos 3015
      pos 3058
      pos 3428
      pos 3613
      pos 3910
      pos 4247
      pos 4601
      pos 4641
      pos 4689
      pos 5021
      pos 5033
      pos 5222
      pos 5300
      pos 5489
      pos 5692
      pos 5862
      pos 6027
      pos 6368
      pos 6763
      pos 7091
      pos 7144
      pos 7201
      pos 7323
      pos 7643
      pos 7744
      pos 7752
      pos 7794
      pos 7802
      pos 7893
      pos 7924
      pos 7934
      pos 8241
      pos 8415
      pos 8432
      pos 8452
      pos 8478
      pos 8499
      pos 8563
      pos 8623
      pos 8657
      pos 8680
      pos 8709
      pos 8765
      pos 8773
      pos 8923
      pos 9024
      pos 9228
      pos 9335
      pos 9405
      pos 9500
      pos 9601
    doc 3
      freq 9
      pos 214
      pos 1561
      pos 1575
      pos 1932
      pos 1936
      pos 1941
      pos 4379
      pos 4609
      pos 4621
    doc 8
      freq 1
      pos 1807
  term ldp's
    doc 1
      freq 1
      pos 1850
  term ldquot
    doc 10
      freq 1
      pos 4812
  term le5rpwenyofxnxjomn
    doc 11
      freq 1
      pos 10251
  term leach
    doc 13
      freq 1
      pos 6891
  term lead
    doc 1
      freq 1
      pos 4162
    doc 2
      freq 1
      pos 3843
    doc 3
      freq 1
      pos 3428
    doc 4
      freq 1
      pos 1236
    doc 12
      freq 3
      pos 3578
      pos 3802
      pos 8593
    doc 13
      freq 2
      pos 3729
      pos 6689
    doc 15
      freq 1
      pos 2283
  term leading
    doc 6
      freq 1
      pos 2317
    doc 7
      freq 1
      pos 248
    doc 9
      freq 1
      pos 272
    doc 10
      freq 1
      pos 5037
    doc 11
      freq 1
      pos 1347
    doc 12
      freq 1
      pos 3137
    doc 14
      freq 4
      pos 2725
      pos 2759
      pos 2783
      pos 2801
    doc 18
      freq 1
      pos 1283
    skipList 
      level 0
        skipDoc 18
        skipDocFP 1330528
        impacts 
          impact 
            freq 1
            norm 95
          impact 
            freq 4
            norm 107
        impactsEnd 
  term leads
    doc 1
      freq 1
      pos 8180
    doc 12
      freq 1
      pos 8615
  term leak
    doc 0
      freq 1
      pos 2785
  term leaked
    doc 0
      freq 3
      pos 560
      pos 3990
      pos 4036
  term leaking
    doc 0
      freq 4
      pos 569
      pos 3512
      pos 4045
      pos 4117
    doc 10
      freq 1
      pos 8139
  term leaky
    doc 6
      freq 1
      pos 2213
  term lear
    doc 7
      freq 14
      pos 4
      pos 195
      pos 582
      pos 946
      pos 1296
      pos 1644
      pos 1818
      pos 2172
      pos 2530
      pos 2885
      pos 2899
      pos 2916
      pos 2932
      pos 3262
    doc 12
      freq 1
      pos 7389
  term learn
    doc 5
      freq 1
      pos 3568
    doc 13
      freq 1
      pos 3278
  term learned
    doc 0
      freq 16
      pos 851
      pos 876
      pos 1358
      pos 3338
      pos 3436
      pos 4499
      pos 8871
      pos 9161
      pos 9473
      pos 9656
      pos 9882
      pos 9964
      pos 10878
      pos 10911
      pos 11753
      pos 12092
    doc 1
      freq 1
      pos 4354
  term learning
    doc 13
      freq 3
      pos 219
      pos 3194
      pos 3233
  term leased
    doc 1
      freq 1
      pos 612
  term least
    doc 0
      freq 15
      pos 2585
      pos 2832
      pos 2881
      pos 3057
      pos 12891
      pos 13145
      pos 13247
      pos 13464
      pos 13562
      pos 13654
      pos 13756
      pos 13829
      pos 13901
      pos 14041
      pos 14170
    doc 1
      freq 1
      pos 8050
    doc 3
      freq 1
      pos 1141
    doc 4
      freq 1
      pos 1021
    doc 7
      freq 1
      pos 1401
    doc 9
      freq 1
      pos 726
    doc 10
      freq 1
      pos 8549
    doc 12
      freq 11
      pos 1118
      pos 1880
      pos 2420
      pos 2779
      pos 3179
      pos 3433
      pos 3566
      pos 3925
      pos 5369
      pos 8436
      pos 9249
    doc 14
      freq 36
      pos 746
      pos 777
      pos 784
      pos 798
      pos 812
      pos 819
      pos 852
      pos 963
      pos 989
      pos 1004
      pos 1011
      pos 1067
      pos 1409
      pos 1437
      pos 1482
      pos 1489
      pos 1503
      pos 1512
      pos 1586
      pos 1613
      pos 1641
      pos 1656
      pos 1663
      pos 1719
      pos 1730
      pos 2566
      pos 3230
      pos 3268
      pos 3274
      pos 4307
      pos 4430
      pos 4437
      pos 4989
      pos 4995
      pos 5012
      pos 5164
    doc 15
      freq 1
      pos 2413
    skipList 
      level 0
        skipDoc 12
        skipDocFP 1332349
        impacts 
          impact 
            freq 1
            norm 95
          impact 
            freq 11
            norm 113
          impact 
            freq 15
            norm 120
        impactsEnd 
  term leave
    doc 3
      freq 1
      pos 2724
    doc 7
      freq 1
      pos 1569
    doc 10
      freq 1
      pos 8909
    doc 12
      freq 1
      pos 9273
  term leaves
    doc 0
      freq 1
      pos 12804
    doc 1
      freq 1
      pos 8324
    doc 10
      freq 1
      pos 11182
  term leaving
    doc 0
      freq 1
      pos 14218
    doc 4
      freq 1
      pos 2435
    doc 12
      freq 2
      pos 8974
      pos 9015
  term lectures
    doc 13
      freq 1
      pos 386
  term led
    doc 2
      freq 2
      pos 2118
      pos 4857
    doc 12
      freq 1
      pos 1026
  term lee
    doc 11
      freq 1
      pos 9676
    doc 13
      freq 1
      pos 6896
  term left
    doc 3
      freq 1
      pos 1051
    doc 4
      freq 1
      pos 909
    doc 7
      freq 1
      pos 1391
    doc 10
      freq 3
      pos 2229
      pos 5920
      pos 11313
    doc 12
      freq 1
      pos 8493
    doc 13
      freq 1
      pos 1242
    doc 14
      freq 22
      pos 522
      pos 748
      pos 786
      pos 821
      pos 854
      pos 965
      pos 1013
      pos 1069
      pos 1411
      pos 1439
      pos 1491
      pos 1588
      pos 1615
      pos 1665
      pos 1721
      pos 3232
      pos 3276
      pos 4309
      pos 4439
      pos 4997
      pos 5014
      pos 5166
    doc 18
      freq 1
      pos 1334
    skipList 
      level 0
        skipDoc 18
        skipDocFP 1334609
        impacts 
          impact 
            freq 1
            norm 97
          impact 
            freq 22
            norm 107
        impactsEnd 
  term leftmost
    doc 18
      freq 2
      pos 1302
      pos 1344
  term legacy
    doc 1
      freq 1
      pos 4879
    doc 6
      freq 1
      pos 486
    doc 13
      freq 1
      pos 522
    doc 15
      freq 1
      pos 3359
  term legal
    doc 0
      freq 1
      pos 1232
    doc 4
      freq 1
      pos 3594
    doc 11
      freq 6
      pos 1653
      pos 4755
      pos 4963
      pos 4990
      pos 8555
      pos 9154
  term legitimat
    doc 0
      freq 1
      pos 16871
    doc 9
      freq 1
      pos 1213
    doc 10
      freq 4
      pos 7835
      pos 8424
      pos 9681
      pos 10148
  term legitimately
    doc 1
      freq 1
      pos 8163
    doc 10
      freq 5
      pos 1034
      pos 1094
      pos 1132
      pos 2866
      pos 9663
  term leifer
    doc 2
      freq 1
      pos 3068
  term lemon
    doc 12
      freq 1
      pos 7178
    doc 15
      freq 3
      pos 3848
      pos 3944
      pos 3979
  term lemonad
    doc 16
      freq 1
      pos 1583
  term len
    doc 0
      freq 1
      pos 11989
  term length
    doc 0
      freq 16
      pos 712
      pos 3217
      pos 3782
      pos 4294
      pos 4602
      pos 6708
      pos 6767
      pos 7615
      pos 7638
      pos 8046
      pos 8068
      pos 11159
      pos 11954
      pos 12246
      pos 12426
      pos 13097
    doc 1
      freq 38
      pos 2493
      pos 2581
      pos 2582
      pos 2769
      pos 3153
      pos 3680
      pos 3683
      pos 3690
      pos 3697
      pos 3760
      pos 3778
      pos 3805
      pos 3816
      pos 3820
      pos 3930
      pos 4041
      pos 4045
      pos 4047
      pos 4050
      pos 4117
      pos 4293
      pos 5105
      pos 5127
      pos 5130
      pos 5273
      pos 5506
      pos 5546
      pos 5744
      pos 5751
      pos 6069
      pos 6071
      pos 6074
      pos 6097
      pos 6103
      pos 6113
      pos 6258
      pos 7162
      pos 7222
    doc 3
      freq 5
      pos 459
      pos 1350
      pos 1939
      pos 2879
      pos 2882
    doc 5
      freq 24
      pos 1271
      pos 1278
      pos 1313
      pos 1321
      pos 1366
      pos 1439
      pos 1616
      pos 1718
      pos 1726
      pos 1751
      pos 1774
      pos 1831
      pos 1842
      pos 1847
      pos 1856
      pos 1921
      pos 1936
      pos 1965
      pos 2087
      pos 2113
      pos 2648
      pos 2710
      pos 2714
      pos 2723
    doc 8
      freq 11
      pos 930
      pos 1008
      pos 1070
      pos 1098
      pos 1104
      pos 1115
      pos 1255
      pos 1302
      pos 1450
      pos 1497
      pos 1527
    doc 10
      freq 7
      pos 2279
      pos 6371
      pos 6671
      pos 7007
      pos 7091
      pos 7153
      pos 7382
    doc 11
      freq 46
      pos 256
      pos 264
      pos 458
      pos 1477
      pos 2000
      pos 2248
      pos 3241
      pos 3361
      pos 3399
      pos 3854
      pos 4034
      pos 4157
      pos 4303
      pos 4345
      pos 4357
      pos 4364
      pos 4488
      pos 4527
      pos 4536
      pos 4598
      pos 4606
      pos 4702
      pos 4944
      pos 5060
      pos 5193
      pos 5350
      pos 5498
      pos 5658
      pos 5824
      pos 5978
      pos 6202
      pos 6995
      pos 7407
      pos 7538
      pos 7772
      pos 7885
      pos 8072
      pos 8235
      pos 8240
      pos 8260
      pos 8344
      pos 8350
      pos 8503
      pos 8632
      pos 9102
      pos 9217
    doc 12
      freq 3
      pos 626
      pos 4403
      pos 5254
    doc 14
      freq 30
      pos 200
      pos 521
      pos 532
      pos 662
      pos 667
      pos 718
      pos 735
      pos 883
      pos 899
      pos 925
      pos 960
      pos 978
      pos 1144
      pos 1158
      pos 1277
      pos 1317
      pos 1357
      pos 1379
      pos 1630
      pos 1737
      pos 2354
      pos 2385
      pos 2407
      pos 2414
      pos 2495
      pos 4173
      pos 4239
      pos 4304
      pos 4426
      pos 4520
    doc 18
      freq 3
      pos 1310
      pos 1349
      pos 1576
    skipList 
      level 0
        skipDoc 12
        skipDocFP 1336550
        impacts 
          impact 
            freq 11
            norm 97
          impact 
            freq 24
            norm 104
          impact 
            freq 38
            norm 113
          impact 
            freq 46
            norm 114
        impactsEnd 
  term lengths
    doc 0
      freq 1
      pos 10680
    doc 14
      freq 1
      pos 2376
    doc 17
      freq 1
      pos 1663
  term les
    doc 0
      freq 1
      pos 15927
    doc 2
      freq 4
      pos 3459
      pos 4350
      pos 4425
      pos 4730
    doc 17
      freq 1
      pos 2391
  term lesl
    doc 2
      freq 1
      pos 6354
  term less
    doc 0
      freq 1
      pos 2588
    doc 2
      freq 1
      pos 3946
    doc 6
      freq 1
      pos 2257
    doc 7
      freq 2
      pos 478
      pos 1618
    doc 10
      freq 3
      pos 658
      pos 1449
      pos 7516
    doc 13
      freq 5
      pos 2453
      pos 2489
      pos 2582
      pos 3909
      pos 4632
    doc 14
      freq 5
      pos 1018
      pos 1670
      pos 2124
      pos 2682
      pos 5330
    doc 18
      freq 1
      pos 1886
    skipList 
      level 0
        skipDoc 18
        skipDocFP 1340233
        impacts 
          impact 
            freq 1
            norm 97
          impact 
            freq 2
            norm 100
          impact 
            freq 5
            norm 107
        impactsEnd 
  term lessen
    doc 13
      freq 1
      pos 4242
  term let
    doc 12
      freq 1
      pos 3440
  term let's
    doc 12
      freq 1
      pos 2825
  term letter
    doc 2
      freq 9
      pos 1415
      pos 2275
      pos 2355
      pos 2433
      pos 2752
      pos 2775
      pos 5753
      pos 5771
      pos 5797
    doc 10
      freq 1
      pos 5122
    doc 14
      freq 2
      pos 2081
      pos 2281
    doc 18
      freq 1
      pos 908
  term letters
    doc 10
      freq 1
      pos 5135
    doc 14
      freq 13
      pos 628
      pos 833
      pos 1035
      pos 1526
      pos 1687
      pos 1892
      pos 1920
      pos 1930
      pos 1938
      pos 2069
      pos 2928
      pos 3569
      pos 4537
  term level
    doc 0
      freq 74
      pos 512
      pos 536
      pos 596
      pos 601
      pos 647
      pos 650
      pos 1251
      pos 1891
      pos 3025
      pos 3315
      pos 3321
      pos 3340
      pos 3373
      pos 3395
      pos 3425
      pos 3482
      pos 4497
      pos 4568
      pos 4635
      pos 4640
      pos 4660
      pos 4745
      pos 4778
      pos 4848
      pos 4880
      pos 4893
      pos 4905
      pos 4979
      pos 5062
      pos 5161
      pos 5191
      pos 5215
      pos 6259
      pos 6264
      pos 6284
      pos 6312
      pos 6391
      pos 6418
      pos 6460
      pos 6488
      pos 6742
      pos 6861
      pos 6885
      pos 7005
      pos 7042
      pos 7134
      pos 7177
      pos 7296
      pos 7699
      pos 7745
      pos 8235
      pos 8265
      pos 8288
      pos 8317
      pos 8375
      pos 8441
      pos 8462
      pos 8474
      pos 8509
      pos 8536
      pos 8567
      pos 8593
      pos 8625
      pos 8657
      pos 8682
      pos 8702
      pos 8727
      pos 8747
      pos 8769
      pos 8787
      pos 11810
      pos 12324
      pos 13957
      pos 13961
    doc 1
      freq 2
      pos 21
      pos 9525
    doc 2
      freq 3
      pos 2037
      pos 2053
      pos 4806
    doc 3
      freq 6
      pos 21
      pos 840
      pos 3103
      pos 4043
      pos 5482
      pos 5890
    doc 4
      freq 1
      pos 660
    doc 5
      freq 2
      pos 3153
      pos 3157
    doc 6
      freq 1
      pos 71
    doc 9
      freq 1
      pos 551
    doc 10
      freq 2
      pos 1785
      pos 7977
    doc 12
      freq 2
      pos 2502
      pos 9237
    doc 13
      freq 3
      pos 2106
      pos 4945
      pos 6663
    doc 14
      freq 3
      pos 2587
      pos 2637
      pos 2668
    doc 16
      freq 1
      pos 1891
    skipList 
      level 0
        skipDoc 9
        skipDocFP 1341730
        impacts 
          impact 
            freq 1
            norm 95
          impact 
            freq 2
            norm 104
          impact 
            freq 6
            norm 107
          impact 
            freq 74
            norm 120
        impactsEnd 
  term level1
    doc 0
      freq 3
      pos 1943
      pos 5879
      pos 9208
  term level1and2
    doc 0
      freq 4
      pos 1947
      pos 2379
      pos 5897
      pos 9199
  term level2
    doc 0
      freq 3
      pos 1945
      pos 5871
      pos 9217
  term level3
    doc 1
      freq 1
      pos 9537
    doc 3
      freq 1
      pos 5902
  term levels
    doc 0
      freq 3
      pos 1931
      pos 2343
      pos 16953
    doc 1
      freq 1
      pos 8906
    doc 3
      freq 1
      pos 4504
    doc 4
      freq 1
      pos 5279
    doc 5
      freq 1
      pos 4134
    doc 8
      freq 1
      pos 1774
    doc 9
      freq 1
      pos 1677
    doc 10
      freq 2
      pos 706
      pos 13128
    doc 13
      freq 3
      pos 2319
      pos 6174
      pos 6747
    doc 17
      freq 2
      pos 178
      pos 2039
    doc 18
      freq 1
      pos 2138
    skipList 
      level 0
        skipDoc 10
        skipDocFP 1344249
        impacts 
          impact 
            freq 1
            norm 95
          impact 
            freq 2
            norm 116
          impact 
            freq 3
            norm 120
        impactsEnd 
  term leverag
    doc 10
      freq 1
      pos 10218
  term leveraging
    doc 3
      freq 1
      pos 1670
  term levi
    doc 2
      freq 1
      pos 3386
  term levkowetz
    doc 2
      freq 2
      pos 2805
      pos 3274
  term lewis
    doc 12
      freq 1
      pos 6812
    doc 18
      freq 2
      pos 2016
      pos 2043
  term lexically
    doc 18
      freq 5
      pos 652
      pos 771
      pos 776
      pos 785
      pos 846
  term lf2liv72a
    doc 11
      freq 1
      pos 9979
  term lfqc
    doc 10
      freq 1
      pos 12514
  term lgolxe6zd3bkfoqojyzrs3mo5byjjsc16cljwvabjz3tbgw
    doc 10
      freq 1
      pos 12575
  term lhy
    doc 11
      freq 1
      pos 10343
  term liabl
    doc 15
      freq 1
      pos 1717
  term liaison
    doc 2
      freq 45
      pos 119
      pos 397
      pos 476
      pos 492
      pos 510
      pos 516
      pos 523
      pos 534
      pos 545
      pos 567
      pos 572
      pos 596
      pos 602
      pos 610
      pos 654
      pos 692
      pos 712
      pos 826
      pos 1414
      pos 1489
      pos 2021
      pos 2240
      pos 2259
      pos 2354
      pos 2364
      pos 2385
      pos 2432
      pos 2446
      pos 2751
      pos 2766
      pos 2774
      pos 2789
      pos 2818
      pos 2821
      pos 4023
      pos 4040
      pos 4045
      pos 4916
      pos 5324
      pos 5673
      pos 5752
      pos 5796
      pos 6000
      pos 6013
      pos 6225
  term liaison1
    doc 2
      freq 2
      pos 1460
      pos 2750
  term liaison2
    doc 2
      freq 2
      pos 1463
      pos 2773
  term liaisonactivities.html
    doc 2
      freq 1
      pos 2825
  term liaisons
    doc 2
      freq 4
      pos 462
      pos 483
      pos 500
      pos 560
  term liberal
    doc 1
      freq 1
      pos 1851
    doc 11
      freq 10
      pos 4118
      pos 5281
      pos 5581
      pos 5747
      pos 5880
      pos 6088
      pos 6317
      pos 6426
      pos 6540
      pos 6586
  term libraries
    doc 12
      freq 2
      pos 6708
      pos 6718
  term library
    doc 12
      freq 5
      pos 3257
      pos 3288
      pos 3324
      pos 3332
      pos 3395
  term licens
    doc 0
      freq 2
      pos 17376
      pos 17451
    doc 1
      freq 2
      pos 9757
      pos 9832
    doc 2
      freq 2
      pos 6554
      pos 6629
    doc 3
      freq 2
      pos 6106
      pos 6181
    doc 4
      freq 2
      pos 6261
      pos 6336
    doc 5
      freq 2
      pos 4591
      pos 4666
    doc 6
      freq 2
      pos 3391
      pos 3466
    doc 7
      freq 2
      pos 3096
      pos 3171
    doc 8
      freq 2
      pos 2313
      pos 2388
    doc 9
      freq 2
      pos 1958
      pos 2033
    doc 10
      freq 2
      pos 13619
      pos 13694
    doc 11
      freq 2
      pos 10780
      pos 10855
    doc 12
      freq 2
      pos 9630
      pos 9705
    doc 13
      freq 2
      pos 7245
      pos 7320
    doc 14
      freq 2
      pos 5711
      pos 5786
    doc 15
      freq 2
      pos 4230
      pos 4305
    doc 16
      freq 2
      pos 2841
      pos 2916
    doc 17
      freq 2
      pos 2565
      pos 2640
    doc 18
      freq 2
      pos 2353
      pos 2428
    skipList 
      level 0
        skipDoc 7
        skipDocFP 1347222
        impacts 
          impact 
            freq 2
            norm 100
        impactsEnd 
        skipDoc 15
        skipDocFP 1347648
        impacts 
          impact 
            freq 2
            norm 95
        impactsEnd 
  term licensed
    doc 2
      freq 1
      pos 2742
  term licenses
    doc 0
      freq 2
      pos 17239
      pos 17435
    doc 1
      freq 2
      pos 9620
      pos 9816
    doc 2
      freq 2
      pos 6417
      pos 6613
    doc 3
      freq 2
      pos 5969
      pos 6165
    doc 4
      freq 2
      pos 6124
      pos 6320
    doc 5
      freq 2
      pos 4454
      pos 4650
    doc 6
      freq 2
      pos 3249
      pos 3450
    doc 7
      freq 2
      pos 2959
      pos 3155
    doc 8
      freq 2
      pos 2176
      pos 2372
    doc 9
      freq 2
      pos 1821
      pos 2017
    doc 10
      freq 2
      pos 13482
      pos 13678
    doc 11
      freq 2
      pos 10643
      pos 10839
    doc 12
      freq 2
      pos 9493
      pos 9689
    doc 13
      freq 2
      pos 7108
      pos 7304
    doc 14
      freq 2
      pos 5574
      pos 5770
    doc 15
      freq 2
      pos 4093
      pos 4289
    doc 16
      freq 2
      pos 2704
      pos 2900
    doc 17
      freq 2
      pos 2428
      pos 2624
    doc 18
      freq 2
      pos 2216
      pos 2412
    skipList 
      level 0
        skipDoc 7
        skipDocFP 1348620
        impacts 
          impact 
            freq 2
            norm 100
        impactsEnd 
        skipDoc 15
        skipDocFP 1349046
        impacts 
          impact 
            freq 2
            norm 95
        impactsEnd 
  term lie
    doc 0
      freq 1
      pos 16592
  term lies
    doc 10
      freq 1
      pos 10338
  term life
    doc 1
      freq 1
      pos 2836
  term lifecycl
    doc 10
      freq 1
      pos 5646
  term lifetim
    doc 0
      freq 1
      pos 11933
    doc 1
      freq 1
      pos 5670
    doc 9
      freq 2
      pos 1577
      pos 1596
    doc 10
      freq 1
      pos 5713
    doc 12
      freq 2
      pos 4826
      pos 4866
    doc 13
      freq 2
      pos 4233
      pos 4237
    doc 17
      freq 1
      pos 1610
  term lifetimes
    doc 10
      freq 1
      pos 3956
    doc 12
      freq 1
      pos 4795
  term lightweight
    doc 13
      freq 1
      pos 2815
  term like
    doc 0
      freq 1
      pos 15900
    doc 2
      freq 4
      pos 260
      pos 3220
      pos 3456
      pos 3973
    doc 4
      freq 1
      pos 348
    doc 5
      freq 2
      pos 4068
      pos 4087
    doc 6
      freq 1
      pos 2612
    doc 10
      freq 14
      pos 644
      pos 1120
      pos 1203
      pos 2954
      pos 2980
      pos 3031
      pos 6603
      pos 7319
      pos 7901
      pos 9342
      pos 9647
      pos 9801
      pos 10511
      pos 12106
    doc 11
      freq 5
      pos 3248
      pos 3287
      pos 4565
      pos 5440
      pos 8295
    doc 12
      freq 6
      pos 2336
      pos 4883
      pos 5343
      pos 6044
      pos 6282
      pos 6537
    doc 13
      freq 1
      pos 6957
    doc 14
      freq 1
      pos 5340
    doc 15
      freq 3
      pos 1249
      pos 2080
      pos 3882
    doc 17
      freq 1
      pos 447
    doc 18
      freq 2
      pos 1141
      pos 2039
    skipList 
      level 0
        skipDoc 12
        skipDocFP 1350651
        impacts 
          impact 
            freq 1
            norm 101
          impact 
            freq 2
            norm 104
          impact 
            freq 4
            norm 108
          impact 
            freq 6
            norm 113
          impact 
            freq 14
            norm 116
        impactsEnd 
  term likelihood
    doc 18
      freq 1
      pos 469
  term likely
    doc 2
      freq 1
      pos 1152
    doc 3
      freq 1
      pos 4224
    doc 6
      freq 1
      pos 2544
    doc 7
      freq 2
      pos 1232
      pos 1250
    doc 9
      freq 1
      pos 1589
    doc 10
      freq 5
      pos 1764
      pos 2179
      pos 3675
      pos 5722
      pos 7664
    doc 11
      freq 1
      pos 7077
    doc 12
      freq 4
      pos 1549
      pos 1609
      pos 1848
      pos 3044
    doc 14
      freq 2
      pos 549
      pos 1845
    doc 15
      freq 2
      pos 968
      pos 2409
    doc 17
      freq 1
      pos 1917
    doc 18
      freq 2
      pos 543
      pos 940
    skipList 
      level 0
        skipDoc 12
        skipDocFP 1352059
        impacts 
          impact 
            freq 1
            norm 95
          impact 
            freq 2
            norm 100
          impact 
            freq 4
            norm 113
          impact 
            freq 5
            norm 116
        impactsEnd 
  term likewis
    doc 9
      freq 1
      pos 770
    doc 11
      freq 1
      pos 8694
    doc 12
      freq 1
      pos 3157
    doc 18
      freq 1
      pos 1858
  term liljenstolp
    doc 1
      freq 1
      pos 9339
    doc 3
      freq 1
      pos 4842
  term lim
    doc 1
      freq 1
      pos 8883
  term limit
    doc 4
      freq 7
      pos 1592
      pos 1825
      pos 1841
      pos 3081
      pos 3123
      pos 3134
      pos 3170
    doc 13
      freq 1
      pos 5477
    doc 16
      freq 3
      pos 1340
      pos 1386
      pos 1408
    doc 17
      freq 1
      pos 1669
    doc 18
      freq 1
      pos 1193
  term limitation
    doc 4
      freq 1
      pos 4002
  term limitations
    doc 2
      freq 1
      pos 2125
    doc 13
      freq 2
      pos 1731
      pos 1932
    doc 15
      freq 1
      pos 1539
    doc 16
      freq 1
      pos 360
  term limited
    doc 0
      freq 1
      pos 17304
    doc 1
      freq 1
      pos 9685
    doc 2
      freq 2
      pos 1859
      pos 6482
    doc 3
      freq 3
      pos 1604
      pos 5166
      pos 6034
    doc 4
      freq 1
      pos 6189
    doc 5
      freq 1
      pos 4519
    doc 6
      freq 1
      pos 3319
    doc 7
      freq 1
      pos 3024
    doc 8
      freq 1
      pos 2241
    doc 9
      freq 3
      pos 306
      pos 317
      pos 1886
    doc 10
      freq 5
      pos 570
      pos 1578
      pos 5880
      pos 11020
      pos 13547
    doc 11
      freq 2
      pos 4870
      pos 10708
    doc 12
      freq 4
      pos 193
      pos 1253
      pos 1722
      pos 9558
    doc 13
      freq 3
      pos 1615
      pos 3905
      pos 7173
    doc 14
      freq 2
      pos 2378
      pos 5639
    doc 15
      freq 1
      pos 4158
    doc 16
      freq 2
      pos 449
      pos 2769
    doc 17
      freq 1
      pos 2493
    doc 18
      freq 1
      pos 2281
    skipList 
      level 0
        skipDoc 7
        skipDocFP 1353923
        impacts 
          impact 
            freq 1
            norm 100
          impact 
            freq 3
            norm 107
        impactsEnd 
        skipDoc 15
        skipDocFP 1354273
        impacts 
          impact 
            freq 3
            norm 95
          impact 
            freq 4
            norm 113
          impact 
            freq 5
            norm 116
        impactsEnd 
  term limiting
    doc 4
      freq 7
      pos 1872
      pos 1891
      pos 1897
      pos 1944
      pos 1982
      pos 4391
      pos 5595
    doc 10
      freq 1
      pos 2799
  term limits
    doc 6
      freq 1
      pos 370
    doc 13
      freq 1
      pos 2537
  term lindholm
    doc 5
      freq 1
      pos 4167
  term lindqvist
    doc 2
      freq 1
      pos 6361
  term line
    doc 0
      freq 1
      pos 17475
    doc 1
      freq 2
      pos 613
      pos 9856
    doc 2
      freq 1
      pos 6653
    doc 3
      freq 1
      pos 6205
    doc 4
      freq 1
      pos 6360
    doc 5
      freq 1
      pos 4690
    doc 6
      freq 2
      pos 1293
      pos 3490
    doc 7
      freq 1
      pos 3195
    doc 8
      freq 1
      pos 2412
    doc 9
      freq 1
      pos 2057
    doc 10
      freq 4
      pos 4904
      pos 6473
      pos 7223
      pos 13718
    doc 11
      freq 17
      pos 308
      pos 318
      pos 366
      pos 898
      pos 912
      pos 941
      pos 984
      pos 1212
      pos 5553
      pos 5567
      pos 5715
      pos 5733
      pos 6726
      pos 6742
      pos 6811
      pos 9232
      pos 10879
    doc 12
      freq 1
      pos 9729
    doc 13
      freq 2
      pos 2652
      pos 7344
    doc 14
      freq 2
      pos 5481
      pos 5810
    doc 15
      freq 1
      pos 4329
    doc 16
      freq 1
      pos 2940
    doc 17
      freq 1
      pos 2664
    doc 18
      freq 8
      pos 30
      pos 354
      pos 375
      pos 452
      pos 460
      pos 502
      pos 534
      pos 2452
    skipList 
      level 0
        skipDoc 7
        skipDocFP 1355782
        impacts 
          impact 
            freq 1
            norm 100
          impact 
            freq 2
            norm 101
        impactsEnd 
        skipDoc 15
        skipDocFP 1356116
        impacts 
          impact 
            freq 1
            norm 95
          impact 
            freq 2
            norm 107
          impact 
            freq 17
            norm 114
        impactsEnd 
  term linear
    doc 10
      freq 1
      pos 5003
  term lines
    doc 10
      freq 1
      pos 12434
    doc 11
      freq 6
      pos 108
      pos 877
      pos 884
      pos 905
      pos 926
      pos 9841
    doc 16
      freq 3
      pos 1163
      pos 1697
      pos 1709
  term link
    doc 0
      freq 12
      pos 689
      pos 883
      pos 889
      pos 903
      pos 912
      pos 1373
      pos 1505
      pos 9195
      pos 11836
      pos 12376
      pos 16264
      pos 16557
    doc 1
      freq 1
      pos 5199
    doc 2
      freq 3
      pos 1955
      pos 2343
      pos 6121
    doc 3
      freq 3
      pos 820
      pos 2940
      pos 3170
    doc 4
      freq 13
      pos 1734
      pos 1769
      pos 2415
      pos 2481
      pos 2485
      pos 2521
      pos 2533
      pos 2557
      pos 2855
      pos 2887
      pos 2948
      pos 2952
      pos 5674
    doc 6
      freq 1
      pos 2608
    doc 7
      freq 3
      pos 1062
      pos 2292
      pos 2639
    doc 10
      freq 1
      pos 1382
    doc 12
      freq 11
      pos 1268
      pos 1295
      pos 1318
      pos 2568
      pos 3375
      pos 3424
      pos 3632
      pos 3836
      pos 3855
      pos 3883
      pos 7779
    doc 13
      freq 1
      pos 942
    skipList 
      level 0
        skipDoc 10
        skipDocFP 1357728
        impacts 
          impact 
            freq 3
            norm 100
          impact 
            freq 13
            norm 108
        impactsEnd 
  term link's
    doc 4
      freq 1
      pos 1918
  term linkag
    doc 0
      freq 1
      pos 10309
  term linked
    doc 10
      freq 1
      pos 13021
  term links
    doc 0
      freq 2
      pos 7880
      pos 7889
    doc 3
      freq 3
      pos 236
      pos 2838
      pos 2857
    doc 4
      freq 1
      pos 5661
    doc 6
      freq 1
      pos 2272
    doc 7
      freq 1
      pos 1967
    doc 13
      freq 1
      pos 4106
  term list
    doc 0
      freq 4
      pos 12613
      pos 14117
      pos 14542
      pos 16185
    doc 1
      freq 2
      pos 8513
      pos 8520
    doc 2
      freq 10
      pos 497
      pos 937
      pos 1012
      pos 1024
      pos 1044
      pos 1664
      pos 4103
      pos 5443
      pos 5477
      pos 5538
    doc 3
      freq 1
      pos 5022
    doc 4
      freq 2
      pos 5745
      pos 5861
    doc 5
      freq 3
      pos 1099
      pos 2697
      pos 3211
    doc 7
      freq 21
      pos 128
      pos 358
      pos 376
      pos 396
      pos 408
      pos 426
      pos 462
      pos 510
      pos 523
      pos 534
      pos 549
      pos 557
      pos 597
      pos 607
      pos 615
      pos 626
      pos 1178
      pos 1265
      pos 1295
      pos 1497
      pos 1783
    doc 9
      freq 1
      pos 1163
    doc 10
      freq 2
      pos 3066
      pos 13246
    doc 11
      freq 1
      pos 4213
    doc 12
      freq 6
      pos 338
      pos 529
      pos 3962
      pos 3978
      pos 4018
      pos 7641
    doc 14
      freq 1
      pos 363
    doc 15
      freq 10
      pos 821
      pos 1292
      pos 1629
      pos 2038
      pos 2191
      pos 2810
      pos 2821
      pos 2872
      pos 2880
      pos 3026
    doc 16
      freq 5
      pos 563
      pos 653
      pos 702
      pos 725
      pos 2384
    doc 17
      freq 3
      pos 552
      pos 739
      pos 2066
    doc 18
      freq 2
      pos 639
      pos 647
    skipList 
      level 0
        skipDoc 9
        skipDocFP 1359380
        impacts 
          impact 
            freq 1
            norm 95
          impact 
            freq 21
            norm 100
        impactsEnd 
        skipDoc 18
        skipDocFP 1360212
        impacts 
          impact 
            freq 2
            norm 97
          impact 
            freq 3
            norm 98
          impact 
            freq 5
            norm 99
          impact 
            freq 10
            norm 104
        impactsEnd 
  term listed
    doc 0
      freq 1
      pos 4595
    doc 5
      freq 1
      pos 3200
    doc 7
      freq 1
      pos 1596
    doc 9
      freq 1
      pos 1054
    doc 11
      freq 1
      pos 1242
    doc 15
      freq 1
      pos 2832
  term listener
    doc 4
      freq 1
      pos 2584
  term listing
    doc 11
      freq 2
      pos 1880
      pos 7708
    doc 15
      freq 1
      pos 2480
  term lists
    doc 2
      freq 2
      pos 971
      pos 1069
    doc 10
      freq 1
      pos 4101
    doc 12
      freq 2
      pos 669
      pos 7651
    doc 15
      freq 5
      pos 273
      pos 930
      pos 2028
      pos 2796
      pos 3709
    doc 18
      freq 1
      pos 191
  term literal
    doc 14
      freq 1
      pos 2337
    doc 16
      freq 20
      pos 240
      pos 571
      pos 583
      pos 697
      pos 745
      pos 783
      pos 1486
      pos 1489
      pos 1492
      pos 1793
      pos 1821
      pos 1838
      pos 1946
      pos 2082
      pos 2174
      pos 2202
      pos 2314
      pos 2410
      pos 2429
      pos 2446
  term literals
    doc 16
      freq 2
      pos 251
      pos 728
  term littl
    doc 3
      freq 1
      pos 3520
    doc 4
      freq 1
      pos 5559
    doc 9
      freq 1
      pos 1395
    doc 10
      freq 1
      pos 9101
    doc 13
      freq 1
      pos 5627
    doc 14
      freq 1
      pos 2815
  term liu
    doc 0
      freq 1
      pos 15947
    doc 15
      freq 1
      pos 3854
  term live
    doc 12
      freq 1
      pos 2056
    doc 13
      freq 6
      pos 214
      pos 2667
      pos 3057
      pos 3064
      pos 3094
      pos 3190
  term lived
    doc 12
      freq 1
      pos 1614
    doc 17
      freq 2
      pos 1595
      pos 1599
  term lixia
    doc 2
      freq 1
      pos 6372
  term ljdd
    doc 11
      freq 1
      pos 10171
  term ljv
    doc 10
      freq 1
      pos 12714
  term lkosy4d2f
    doc 10
      freq 1
      pos 12563
  term llc
    doc 1
      freq 2
      pos 24
      pos 9528
    doc 3
      freq 2
      pos 24
      pos 5893
  term lldcf3ijzanpbynm
    doc 11
      freq 1
      pos 9993
  term lmartin
    doc 1
      freq 1
      pos 9520
    doc 3
      freq 1
      pos 5885
    doc 8
      freq 1
      pos 2144
  term lmsc
    doc 2
      freq 1
      pos 2883
  term lmtf5doesp0lof6q4k5lsnryonnhebxz9ujcp
    doc 10
      freq 1
      pos 12615
  term loa
    doc 2
      freq 1
      pos 6350
    doc 3
      freq 2
      pos 4987
      pos 4992
  term load
    doc 3
      freq 2
      pos 3302
      pos 5741
    doc 6
      freq 3
      pos 953
      pos 1001
      pos 2958
    doc 12
      freq 5
      pos 222
      pos 1627
      pos 1671
      pos 1684
      pos 3498
    doc 13
      freq 1
      pos 4266
    doc 15
      freq 5
      pos 231
      pos 1283
      pos 1303
      pos 1328
      pos 2013
  term loaded
    doc 10
      freq 1
      pos 4561
    doc 12
      freq 1
      pos 8057
  term local
    doc 0
      freq 4
      pos 6534
      pos 6676
      pos 13971
      pos 14000
    doc 1
      freq 7
      pos 3465
      pos 3557
      pos 4461
      pos 4628
      pos 6670
      pos 8463
      pos 8844
    doc 2
      freq 9
      pos 2484
      pos 2505
      pos 2534
      pos 2560
      pos 2570
      pos 2590
      pos 2631
      pos 2710
      pos 3428
    doc 3
      freq 9
      pos 2477
      pos 2685
      pos 4421
      pos 4455
      pos 4462
      pos 5324
      pos 5336
      pos 5380
      pos 5411
    doc 4
      freq 1
      pos 2416
    doc 5
      freq 8
      pos 1662
      pos 1972
      pos 2295
      pos 2338
      pos 2371
      pos 2394
      pos 2403
      pos 2410
    doc 6
      freq 2
      pos 2305
      pos 2324
    doc 7
      freq 2
      pos 870
      pos 2280
    doc 8
      freq 5
      pos 1312
      pos 1598
      pos 1606
      pos 1614
      pos 1623
    doc 10
      freq 11
      pos 1229
      pos 1275
      pos 1300
      pos 1363
      pos 2736
      pos 3157
      pos 3870
      pos 7581
      pos 7652
      pos 9202
      pos 13070
    doc 12
      freq 25
      pos 450
      pos 740
      pos 1265
      pos 1269
      pos 1274
      pos 1279
      pos 1290
      pos 1296
      pos 1314
      pos 3376
      pos 3425
      pos 3884
      pos 6414
      pos 7322
      pos 7415
      pos 7895
      pos 7901
      pos 7910
      pos 7923
      pos 7928
      pos 7948
      pos 7993
      pos 8010
      pos 8022
      pos 8035
    doc 13
      freq 3
      pos 1809
      pos 2638
      pos 2647
    doc 17
      freq 1
      pos 1044
    skipList 
      level 0
        skipDoc 7
        skipDocFP 1364348
        impacts 
          impact 
            freq 2
            norm 100
          impact 
            freq 8
            norm 104
          impact 
            freq 9
            norm 107
        impactsEnd 
  term locales
    doc 6
      freq 1
      pos 963
  term localized
    doc 6
      freq 1
      pos 2579
  term locally
    doc 1
      freq 5
      pos 6565
      pos 6605
      pos 6707
      pos 6722
      pos 6734
    doc 3
      freq 1
      pos 5320
    doc 5
      freq 1
      pos 2319
    doc 12
      freq 2
      pos 7920
      pos 8040
    doc 13
      freq 1
      pos 2495
    doc 17
      freq 1
      pos 2254
  term locals
    doc 12
      freq 2
      pos 3837
      pos 3856
  term locat
    doc 10
      freq 1
      pos 7670
    doc 17
      freq 1
      pos 1235
  term located
    doc 4
      freq 1
      pos 5060
    doc 5
      freq 1
      pos 3575
    doc 12
      freq 3
      pos 6199
      pos 6269
      pos 6411
    doc 15
      freq 1
      pos 3635
    doc 16
      freq 1
      pos 1659
  term locating
    doc 10
      freq 1
      pos 13161
  term location
    doc 4
      freq 1
      pos 3425
    doc 7
      freq 3
      pos 1875
      pos 1901
      pos 1955
    doc 12
      freq 2
      pos 6183
      pos 7502
    doc 13
      freq 3
      pos 1016
      pos 2808
      pos 2813
    doc 14
      freq 1
      pos 5419
    doc 15
      freq 1
      pos 2247
  term locations
    doc 6
      freq 1
      pos 2730
    doc 10
      freq 1
      pos 6143
  term locators
    doc 7
      freq 2
      pos 2613
      pos 2708
  term loecuuqk6t35n4zta2qdg5vg7g6wxrm8llx0da24s3a19vollxb9d7ncxbtz
    doc 11
      freq 1
      pos 10232
  term logging
    doc 6
      freq 1
      pos 1109
  term logic
    doc 11
      freq 2
      pos 7017
      pos 7164
  term logical
    doc 0
      freq 4
      pos 3833
      pos 4333
      pos 10422
      pos 11197
    doc 3
      freq 1
      pos 918
    doc 10
      freq 1
      pos 3799
    doc 13
      freq 4
      pos 1345
      pos 1364
      pos 2201
      pos 4920
  term logically
    doc 0
      freq 1
      pos 10687
    doc 10
      freq 1
      pos 1149
    doc 12
      freq 1
      pos 2004
  term login
    doc 12
      freq 1
      pos 5116
    doc 16
      freq 1
      pos 988
  term logout
    doc 7
      freq 1
      pos 1851
  term logs
    doc 12
      freq 1
      pos 4985
  term london
    doc 14
      freq 1
      pos 5532
  term long
    doc 0
      freq 1
      pos 6143
    doc 1
      freq 1
      pos 913
    doc 4
      freq 2
      pos 1934
      pos 1937
    doc 6
      freq 8
      pos 629
      pos 1088
      pos 1102
      pos 1105
      pos 1339
      pos 1418
      pos 1454
      pos 1470
    doc 7
      freq 1
      pos 387
    doc 9
      freq 1
      pos 729
    doc 10
      freq 1
      pos 11322
    doc 11
      freq 20
      pos 107
      pos 118
      pos 198
      pos 876
      pos 1089
      pos 1266
      pos 2709
      pos 2729
      pos 2741
      pos 2745
      pos 2757
      pos 2767
      pos 2775
      pos 2821
      pos 2835
      pos 2892
      pos 2899
      pos 2906
      pos 2914
      pos 3144
    doc 12
      freq 10
      pos 1877
      pos 2443
      pos 3637
      pos 3804
      pos 4499
      pos 4509
      pos 5768
      pos 6611
      pos 6630
      pos 8778
    doc 13
      freq 1
      pos 1567
    doc 14
      freq 1
      pos 881
    doc 15
      freq 1
      pos 3583
    doc 17
      freq 2
      pos 1594
      pos 1598
    skipList 
      level 0
        skipDoc 11
        skipDocFP 1368488
        impacts 
          impact 
            freq 1
            norm 95
          impact 
            freq 8
            norm 101
          impact 
            freq 20
            norm 114
        impactsEnd 
  term longcallid
    doc 11
      freq 1
      pos 2883
  term longer
    doc 1
      freq 1
      pos 7440
    doc 6
      freq 2
      pos 547
      pos 2381
    doc 10
      freq 3
      pos 5539
      pos 5709
      pos 7720
    doc 11
      freq 1
      pos 885
    doc 12
      freq 3
      pos 4788
      pos 5730
      pos 6742
    doc 14
      freq 4
      pos 1398
      pos 1420
      pos 1575
      pos 1597
    doc 15
      freq 3
      pos 1513
      pos 2418
      pos 3557
  term longest
    doc 14
      freq 3
      pos 512
      pos 2417
      pos 2463
  term longparam
    doc 11
      freq 1
      pos 2824
  term longreq
    doc 11
      freq 1
      pos 2793
  term longreq.on
    doc 11
      freq 1
      pos 2877
  term look
    doc 11
      freq 4
      pos 3247
      pos 3286
      pos 7324
      pos 7359
    doc 12
      freq 5
      pos 2175
      pos 4968
      pos 6536
      pos 8016
      pos 9145
  term looked
    doc 7
      freq 1
      pos 1608
    doc 12
      freq 1
      pos 8926
  term looking
    doc 12
      freq 7
      pos 1750
      pos 3264
      pos 3307
      pos 3452
      pos 4732
      pos 5060
      pos 5814
  term looks
    doc 10
      freq 2
      pos 6602
      pos 7318
    doc 12
      freq 4
      pos 683
      pos 733
      pos 2681
      pos 6593
  term lookup
    doc 10
      freq 1
      pos 12912
    doc 12
      freq 4
      pos 3506
      pos 3572
      pos 3847
      pos 5211
  term lookups
    doc 12
      freq 10
      pos 328
      pos 1867
      pos 3249
      pos 3585
      pos 3674
      pos 3833
      pos 3878
      pos 5246
      pos 6672
      pos 8063
  term loop
    doc 4
      freq 1
      pos 3163
  term loops
    doc 12
      freq 1
      pos 2229
  term loose
    doc 5
      freq 2
      pos 128
      pos 489
    doc 10
      freq 1
      pos 4565
  term lortz
    doc 2
      freq 1
      pos 2303
  term lose
    doc 13
      freq 1
      pos 6509
    doc 15
      freq 1
      pos 1068
  term loss
    doc 3
      freq 2
      pos 1565
      pos 3044
    doc 5
      freq 5
      pos 21
      pos 91
      pos 123
      pos 4197
      pos 4222
    doc 6
      freq 17
      pos 223
      pos 242
      pos 338
      pos 902
      pos 970
      pos 985
      pos 1158
      pos 1487
      pos 1516
      pos 2038
      pos 2042
      pos 2109
      pos 2162
      pos 2183
      pos 2334
      pos 2699
      pos 2702
    doc 12
      freq 1
      pos 2745
    doc 17
      freq 1
      pos 1493
  term lost
    doc 3
      freq 2
      pos 1455
      pos 1645
    doc 6
      freq 7
      pos 938
      pos 2048
      pos 2114
      pos 2120
      pos 2432
      pos 2445
      pos 2708
    doc 15
      freq 2
      pos 2898
      pos 2926
  term lot
    doc 12
      freq 2
      pos 6488
      pos 6721
  term louis
    doc 11
      freq 1
      pos 10558
  term low
    doc 0
      freq 1
      pos 4918
    doc 1
      freq 2
      pos 148
      pos 655
    doc 4
      freq 1
      pos 1973
    doc 5
      freq 1
      pos 107
    doc 7
      freq 1
      pos 1964
    doc 9
      freq 2
      pos 157
      pos 520
    doc 12
      freq 1
      pos 2743
  term lower
    doc 7
      freq 1
      pos 2053
    doc 12
      freq 1
      pos 2457
    doc 13
      freq 1
      pos 5476
    doc 14
      freq 2
      pos 1890
      pos 2617
  term lowercas
    doc 10
      freq 1
      pos 5138
    doc 14
      freq 4
      pos 638
      pos 1927
      pos 2207
      pos 2215
  term lowering
    doc 0
      freq 1
      pos 16038
    doc 12
      freq 1
      pos 4876
  term lowest
    doc 0
      freq 3
      pos 8472
      pos 8534
      pos 8591
    doc 1
      freq 1
      pos 5183
  term lp6hql20i5ouop
    doc 11
      freq 1
      pos 10109
  term lpc
    doc 11
      freq 19
      pos 1565
      pos 2283
      pos 3201
      pos 3434
      pos 4077
      pos 4342
      pos 4523
      pos 4737
      pos 5228
      pos 5385
      pos 5533
      pos 5693
      pos 6013
      pos 6237
      pos 6923
      pos 7261
      pos 8217
      pos 8546
      pos 9141
  term lqtgnfq
    doc 11
      freq 1
      pos 10358
  term lr
    doc 11
      freq 2
      pos 1503
      pos 5455
  term ls
    doc 2
      freq 1
      pos 2386
  term lsp
    doc 0
      freq 52
      pos 928
      pos 1508
      pos 1530
      pos 1541
      pos 1627
      pos 3427
      pos 3484
      pos 4598
      pos 4626
      pos 7039
      pos 7071
      pos 7457
      pos 7591
      pos 8617
      pos 11688
      pos 11723
      pos 11746
      pos 11813
      pos 11832
      pos 11858
      pos 11887
      pos 11914
      pos 11938
      pos 11957
      pos 11976
      pos 11979
      pos 11983
      pos 11995
      pos 12011
      pos 12030
      pos 12085
      pos 12142
      pos 12189
      pos 12211
      pos 12515
      pos 12589
      pos 12936
      pos 12960
      pos 13014
      pos 13309
      pos 13352
      pos 13366
      pos 13876
      pos 13959
      pos 13963
      pos 13978
      pos 14018
      pos 14089
      pos 14267
      pos 14292
      pos 14341
      pos 15789
    doc 1
      freq 9
      pos 932
      pos 1268
      pos 1387
      pos 1511
      pos 2866
      pos 2869
      pos 2873
      pos 4714
      pos 4733
    doc 3
      freq 2
      pos 5494
      pos 5547
  term lspid
    doc 0
      freq 2
      pos 4845
      pos 13059
  term lspl1databaseoverloads
    doc 0
      freq 1
      pos 7464
  term lsps
    doc 0
      freq 25
      pos 526
      pos 2559
      pos 2825
      pos 2912
      pos 3342
      pos 3375
      pos 3942
      pos 3973
      pos 4768
      pos 4841
      pos 4948
      pos 5158
      pos 5918
      pos 5988
      pos 6040
      pos 6999
      pos 7060
      pos 7327
      pos 7329
      pos 7357
      pos 7726
      pos 8650
      pos 11698
      pos 12060
      pos 14353
    doc 1
      freq 3
      pos 3370
      pos 3568
      pos 4782
    doc 3
      freq 1
      pos 5534
  term lsr
    doc 1
      freq 3
      pos 1202
      pos 1206
      pos 1740
  term ltd
    doc 6
      freq 1
      pos 3006
    doc 13
      freq 1
      pos 6993
  term ltgtrur
    doc 11
      freq 2
      pos 5311
      pos 5330
  term ltp5r
    doc 11
      freq 1
      pos 9995
  term lu4clmomfkvp
    doc 11
      freq 1
      pos 10365
  term luca
    doc 1
      freq 1
      pos 9505
    doc 3
      freq 1
      pos 5869
    doc 8
      freq 1
      pos 2129
  term lucent
    doc 11
      freq 1
      pos 9613
  term lul
    doc 12
      freq 1
      pos 7925
  term luminous
    doc 3
      freq 1
      pos 4947
  term luminous.com
    doc 3
      freq 1
      pos 4958
  term luo
    doc 1
      freq 1
      pos 8885
    doc 8
      freq 1
      pos 2081
  term luoma
    doc 13
      freq 3
      pos 17
      pos 6859
      pos 7024
  term lws
    doc 10
      freq 1
      pos 5005
    doc 11
      freq 8
      pos 177
      pos 301
      pos 1226
      pos 2610
      pos 2631
      pos 5406
      pos 5411
      pos 5436
  term lwsdisp
    doc 11
      freq 2
      pos 2673
      pos 2693
  term lwsrur
    doc 11
      freq 1
      pos 5451
  term lwsruri.asdfasdoeoi2323
    doc 11
      freq 1
      pos 5475
  term lwsstart
    doc 11
      freq 1
      pos 5617
  term lwsstart.dfknq234oi243099adsdfnawe3
    doc 11
      freq 1
      pos 5636
  term lxlccoj2trssxx0aiqz4dlvxh0blmsrxh0oaron
    doc 11
      freq 1
      pos 10473
  term lxwt1cdiyvpmbchdbakeampgkfj
    doc 10
      freq 1
      pos 6868
  term lynn
    doc 4
      freq 1
      pos 5481
  term m
    doc 0
      freq 2
      pos 15940
      pos 17110
    doc 1
      freq 1
      pos 9056
    doc 2
      freq 2
      pos 3075
      pos 3475
    doc 3
      freq 1
      pos 4717
    doc 4
      freq 1
      pos 21
    doc 5
      freq 7
      pos 4170
      pos 4212
      pos 4243
      pos 4303
      pos 4329
      pos 4355
      pos 4359
    doc 8
      freq 3
      pos 1834
      pos 1945
      pos 2044
    doc 10
      freq 10
      pos 6394
      pos 6531
      pos 6694
      pos 6858
      pos 12410
      pos 12647
      pos 12769
      pos 13104
      pos 13292
      pos 13341
    doc 11
      freq 46
      pos 1522
      pos 1549
      pos 1556
      pos 2267
      pos 2274
      pos 3185
      pos 3192
      pos 3418
      pos 3425
      pos 4061
      pos 4068
      pos 4326
      pos 4333
      pos 4507
      pos 4514
      pos 4721
      pos 4728
      pos 5212
      pos 5219
      pos 5369
      pos 5376
      pos 5517
      pos 5524
      pos 5677
      pos 5684
      pos 5997
      pos 6004
      pos 6221
      pos 6228
      pos 6907
      pos 6914
      pos 7245
      pos 7252
      pos 8201
      pos 8208
      pos 8530
      pos 8537
      pos 8944
      pos 9125
      pos 9132
      pos 9302
      pos 9643
      pos 9815
      pos 9991
      pos 10010
      pos 10262
    doc 12
      freq 10
      pos 7057
      pos 7183
      pos 7267
      pos 7347
      pos 7557
      pos 7745
      pos 7761
      pos 7813
      pos 7827
      pos 7862
    doc 13
      freq 3
      pos 6759
      pos 6773
      pos 6842
    doc 14
      freq 1
      pos 5434
    doc 15
      freq 1
      pos 3949
    doc 16
      freq 3
      pos 2524
      pos 2547
      pos 2593
    doc 18
      freq 3
      pos 2065
      pos 2086
      pos 2109
    skipList 
      level 0
        skipDoc 10
        skipDocFP 1377388
        impacts 
          impact 
            freq 3
            norm 97
          impact 
            freq 7
            norm 104
          impact 
            freq 10
            norm 116
        impactsEnd 
  term m1btjgu7hu
    doc 11
      freq 1
      pos 10107
  term m2ti7ix4caqctaufx5clegq
    doc 10
      freq 1
      pos 6834
  term m48r
    doc 10
      freq 1
      pos 6855
  term m4jccbjkgtalihppmtovpb7c
    doc 11
      freq 1
      pos 10102
  term m7dvqxkdb7x9
    doc 11
      freq 1
      pos 10243
  term m8x
    doc 11
      freq 1
      pos 10450
  term m9o7t8rkqkslreqqds6lrgzghffm
    doc 11
      freq 1
      pos 9968
  term m9tie75xddtiokhl6nts
    doc 11
      freq 1
      pos 10122
  term mac
    doc 2
      freq 4
      pos 2546
      pos 2645
      pos 2679
      pos 6087
    doc 3
      freq 7
      pos 461
      pos 469
      pos 659
      pos 662
      pos 936
      pos 3386
      pos 4135
    doc 5
      freq 16
      pos 148
      pos 483
      pos 1247
      pos 1328
      pos 1338
      pos 1373
      pos 1932
      pos 1939
      pos 2109
      pos 2123
      pos 3953
      pos 3954
      pos 3990
      pos 4045
      pos 4056
      pos 4057
    doc 15
      freq 1
      pos 2543
  term macdonald
    doc 11
      freq 1
      pos 9440
  term machin
    doc 0
      freq 2
      pos 2125
      pos 2143
    doc 2
      freq 9
      pos 300
      pos 2076
      pos 4894
      pos 5008
      pos 5117
      pos 5151
      pos 5187
      pos 5217
      pos 5305
  term machines
    doc 2
      freq 1
      pos 3338
  term macintosh
    doc 7
      freq 1
      pos 2620
  term macmim
    doc 7
      freq 1
      pos 2622
  term macro
    doc 7
      freq 1
      pos 1858
  term maddr
    doc 11
      freq 1
      pos 9264
  term made
    doc 0
      freq 5
      pos 3271
      pos 17393
      pos 17426
      pos 17438
      pos 17446
    doc 1
      freq 4
      pos 9774
      pos 9807
      pos 9819
      pos 9827
    doc 2
      freq 7
      pos 1864
      pos 5403
      pos 5879
      pos 6571
      pos 6604
      pos 6616
      pos 6624
    doc 3
      freq 4
      pos 6123
      pos 6156
      pos 6168
      pos 6176
    doc 4
      freq 7
      pos 4976
      pos 5548
      pos 5762
      pos 6278
      pos 6311
      pos 6323
      pos 6331
    doc 5
      freq 5
      pos 186
      pos 4608
      pos 4641
      pos 4653
      pos 4661
    doc 6
      freq 4
      pos 3408
      pos 3441
      pos 3453
      pos 3461
    doc 7
      freq 4
      pos 3113
      pos 3146
      pos 3158
      pos 3166
    doc 8
      freq 4
      pos 2330
      pos 2363
      pos 2375
      pos 2383
    doc 9
      freq 4
      pos 1975
      pos 2008
      pos 2020
      pos 2028
    doc 10
      freq 8
      pos 6593
      pos 7309
      pos 9821
      pos 10703
      pos 13636
      pos 13669
      pos 13681
      pos 13689
    doc 11
      freq 4
      pos 10797
      pos 10830
      pos 10842
      pos 10850
    doc 12
      freq 6
      pos 1214
      pos 6191
      pos 9647
      pos 9680
      pos 9692
      pos 9700
    doc 13
      freq 4
      pos 7262
      pos 7295
      pos 7307
      pos 7315
    doc 14
      freq 4
      pos 5728
      pos 5761
      pos 5773
      pos 5781
    doc 15
      freq 6
      pos 324
      pos 725
      pos 4247
      pos 4280
      pos 4292
      pos 4300
    doc 16
      freq 4
      pos 2858
      pos 2891
      pos 2903
      pos 2911
    doc 17
      freq 4
      pos 2582
      pos 2615
      pos 2627
      pos 2635
    doc 18
      freq 5
      pos 136
      pos 2370
      pos 2403
      pos 2415
      pos 2423
    skipList 
      level 0
        skipDoc 7
        skipDocFP 1381025
        impacts 
          impact 
            freq 4
            norm 100
          impact 
            freq 5
            norm 104
          impact 
            freq 7
            norm 108
        impactsEnd 
        skipDoc 15
        skipDocFP 1381812
        impacts 
          impact 
            freq 4
            norm 95
          impact 
            freq 6
            norm 104
          impact 
            freq 8
            norm 116
        impactsEnd 
  term madsen
    doc 3
      freq 1
      pos 4701
  term mae
    doc 1
      freq 1
      pos 9343
    doc 3
      freq 1
      pos 4846
  term magic
    doc 10
      freq 1
      pos 11095
  term magnus
    doc 13
      freq 1
      pos 6976
  term mahy
    doc 10
      freq 1
      pos 12112
    doc 11
      freq 1
      pos 9480
  term mail
    doc 2
      freq 1
      pos 589
    doc 7
      freq 8
      pos 801
      pos 816
      pos 830
      pos 844
      pos 2211
      pos 2226
      pos 2240
      pos 2254
    doc 12
      freq 4
      pos 2172
      pos 2178
      pos 2195
      pos 7102
    doc 13
      freq 1
      pos 474
    doc 16
      freq 2
      pos 1084
      pos 2577
  term mailbox
    doc 16
      freq 8
      pos 433
      pos 545
      pos 607
      pos 649
      pos 824
      pos 959
      pos 961
      pos 970
  term mailing
    doc 2
      freq 7
      pos 936
      pos 970
      pos 1011
      pos 1068
      pos 4102
      pos 5442
      pos 5537
    doc 7
      freq 6
      pos 127
      pos 357
      pos 461
      pos 509
      pos 548
      pos 1782
    doc 12
      freq 1
      pos 7640
    doc 16
      freq 1
      pos 2383
  term main
    doc 1
      freq 1
      pos 8212
    doc 2
      freq 2
      pos 3621
      pos 4345
    doc 8
      freq 1
      pos 232
    doc 12
      freq 1
      pos 5118
    doc 13
      freq 1
      pos 2062
    doc 15
      freq 1
      pos 1384
  term mainly
    doc 0
      freq 1
      pos 345
    doc 12
      freq 1
      pos 1741
  term mains
    doc 13
      freq 1
      pos 2071
  term maintain
    doc 1
      freq 2
      pos 1307
      pos 1909
    doc 7
      freq 1
      pos 578
    doc 9
      freq 1
      pos 848
    doc 10
      freq 1
      pos 2842
    doc 11
      freq 1
      pos 9174
    doc 13
      freq 1
      pos 4087
    doc 15
      freq 1
      pos 1902
    doc 17
      freq 1
      pos 1554
    skipList 
      level 0
        skipDoc 17
        skipDocFP 1385006
        impacts 
          impact 
            freq 1
            norm 95
          impact 
            freq 2
            norm 113
        impactsEnd 
  term maintained
    doc 0
      freq 1
      pos 739
    doc 12
      freq 3
      pos 896
      pos 4383
      pos 4519
    doc 15
      freq 1
      pos 3313
  term maintaining
    doc 1
      freq 6
      pos 173
      pos 747
      pos 949
      pos 2206
      pos 2257
      pos 7943
    doc 3
      freq 1
      pos 1099
    doc 10
      freq 1
      pos 2634
    doc 13
      freq 1
      pos 664
    doc 14
      freq 1
      pos 361
    doc 15
      freq 1
      pos 3481
  term maintains
    doc 1
      freq 2
      pos 7757
      pos 7807
    doc 14
      freq 1
      pos 1322
  term maintenanc
    doc 1
      freq 2
      pos 38
      pos 968
    doc 3
      freq 2
      pos 2273
      pos 4373
    doc 8
      freq 1
      pos 1801
    doc 13
      freq 1
      pos 5338
  term major
    doc 2
      freq 1
      pos 1143
    doc 6
      freq 1
      pos 436
  term majority
    doc 10
      freq 1
      pos 7420
    doc 12
      freq 1
      pos 5131
  term make
    doc 0
      freq 1
      pos 925
    doc 1
      freq 4
      pos 2800
      pos 4709
      pos 8449
      pos 8732
    doc 2
      freq 1
      pos 1142
    doc 4
      freq 3
      pos 4916
      pos 5556
      pos 5924
    doc 5
      freq 2
      pos 3112
      pos 3618
    doc 10
      freq 5
      pos 5700
      pos 8265
      pos 9332
      pos 10675
      pos 11068
    doc 11
      freq 1
      pos 674
    doc 12
      freq 3
      pos 939
      pos 4605
      pos 5199
    doc 13
      freq 2
      pos 2341
      pos 4760
    doc 14
      freq 2
      pos 657
      pos 2654
    doc 15
      freq 2
      pos 1319
      pos 3509
    doc 17
      freq 2
      pos 373
      pos 1831
    doc 18
      freq 2
      pos 318
      pos 1678
    skipList 
      level 0
        skipDoc 12
        skipDocFP 1386537
        impacts 
          impact 
            freq 2
            norm 104
          impact 
            freq 3
            norm 108
          impact 
            freq 4
            norm 113
          impact 
            freq 5
            norm 116
        impactsEnd 
  term makes
    doc 4
      freq 1
      pos 2910
    doc 7
      freq 1
      pos 449
    doc 10
      freq 4
      pos 4738
      pos 10254
      pos 10714
      pos 10896
    doc 11
      freq 2
      pos 659
      pos 5133
    doc 12
      freq 5
      pos 1996
      pos 2475
      pos 4612
      pos 5181
      pos 9194
    doc 14
      freq 1
      pos 2009
    doc 15
      freq 1
      pos 165
    doc 17
      freq 1
      pos 191
    doc 18
      freq 1
      pos 1702
    skipList 
      level 0
        skipDoc 17
        skipDocFP 1387645
        impacts 
          impact 
            freq 1
            norm 98
          impact 
            freq 5
            norm 113
        impactsEnd 
  term makf3doq1iksueevbcodghltu6t5rsv
    doc 11
      freq 1
      pos 9997
  term makga1uecawcr0exedaobgnvbacmb0f0bgfudgexdtalbgnvbaombelfveyxhda
    doc 10
      freq 1
      pos 6249
  term makga1uecawctvmxdzanbgnvbacmbkjpbg94atenmasga1uecgwesuvurjebmbkg
    doc 10
      freq 1
      pos 6881
  term making
    doc 4
      freq 1
      pos 1457
    doc 10
      freq 1
      pos 11384
    doc 14
      freq 1
      pos 2114
    doc 16
      freq 2
      pos 496
      pos 1063
    doc 18
      freq 1
      pos 336
  term malformed
    doc 0
      freq 3
      pos 12694
      pos 12740
      pos 14305
    doc 11
      freq 12
      pos 296
      pos 4202
      pos 5401
      pos 5576
      pos 5742
      pos 5850
      pos 6062
      pos 6264
      pos 6390
      pos 6499
      pos 6649
      pos 7082
  term malicious
    doc 4
      freq 3
      pos 4407
      pos 4423
      pos 4484
    doc 9
      freq 1
      pos 866
    doc 10
      freq 1
      pos 8706
    doc 11
      freq 1
      pos 9334
    doc 13
      freq 1
      pos 6483
    doc 16
      freq 1
      pos 1374
    doc 17
      freq 2
      pos 1735
      pos 1752
  term malis
    doc 1
      freq 3
      pos 8975
      pos 9080
      pos 9284
    doc 2
      freq 1
      pos 2976
    doc 3
      freq 3
      pos 4628
      pos 4643
      pos 4753
    doc 8
      freq 4
      pos 1831
      pos 1846
      pos 1865
      pos 1969
  term man
    doc 2
      freq 2
      pos 2669
      pos 2880
    doc 5
      freq 4
      pos 303
      pos 2973
      pos 3001
      pos 3465
    doc 10
      freq 6
      pos 9175
      pos 9327
      pos 9435
      pos 9849
      pos 9879
      pos 10182
  term manag
    doc 0
      freq 7
      pos 432
      pos 4116
      pos 15468
      pos 15582
      pos 15715
      pos 15757
      pos 16001
    doc 9
      freq 1
      pos 1027
    doc 10
      freq 2
      pos 2827
      pos 9818
    doc 12
      freq 3
      pos 4901
      pos 5607
      pos 9408
    doc 13
      freq 1
      pos 4750
  term manageabl
    doc 12
      freq 1
      pos 4255
  term managed
    doc 0
      freq 2
      pos 222
      pos 353
    doc 2
      freq 8
      pos 2908
      pos 2929
      pos 2999
      pos 3215
      pos 3232
      pos 3251
      pos 3377
      pos 3393
    doc 4
      freq 1
      pos 4772
    doc 7
      freq 12
      pos 878
      pos 987
      pos 1024
      pos 1057
      pos 2009
      pos 2288
      pos 2306
      pos 2323
      pos 2342
      pos 2475
      pos 2569
      pos 2634
    doc 10
      freq 2
      pos 1512
      pos 10458
    doc 12
      freq 2
      pos 4808
      pos 5138
    doc 15
      freq 6
      pos 382
      pos 479
      pos 489
      pos 602
      pos 737
      pos 779
  term management
    doc 0
      freq 27
      pos 17
      pos 96
      pos 104
      pos 145
      pos 196
      pos 211
      pos 233
      pos 247
      pos 264
      pos 305
      pos 751
      pos 1126
      pos 1192
      pos 5256
      pos 6162
      pos 9352
      pos 15893
      pos 15979
      pos 16096
      pos 16169
      pos 16528
      pos 16931
      pos 17002
      pos 17028
      pos 17031
      pos 17049
      pos 17189
    doc 2
      freq 28
      pos 75
      pos 222
      pos 521
      pos 568
      pos 597
      pos 1235
      pos 1285
      pos 1390
      pos 1406
      pos 1673
      pos 2147
      pos 2237
      pos 2331
      pos 2811
      pos 3691
      pos 3734
      pos 3841
      pos 3919
      pos 4135
      pos 4142
      pos 4172
      pos 4197
      pos 4205
      pos 4451
      pos 4966
      pos 5730
      pos 5769
      pos 6151
    doc 3
      freq 10
      pos 231
      pos 255
      pos 2833
      pos 3216
      pos 3220
      pos 3226
      pos 3237
      pos 3309
      pos 4543
      pos 4601
    doc 5
      freq 4
      pos 226
      pos 604
      pos 850
      pos 2227
    doc 7
      freq 13
      pos 721
      pos 822
      pos 969
      pos 1040
      pos 1049
      pos 2058
      pos 2232
      pos 2421
      pos 2549
      pos 2585
      pos 2595
      pos 2598
      pos 2626
    doc 9
      freq 9
      pos 103
      pos 128
      pos 673
      pos 691
      pos 702
      pos 773
      pos 1023
      pos 1034
      pos 1713
    doc 10
      freq 3
      pos 23
      pos 415
      pos 5647
    doc 12
      freq 1
      pos 1157
    doc 15
      freq 2
      pos 223
      pos 1105
    doc 17
      freq 1
      pos 1482
    skipList 
      level 0
        skipDoc 12
        skipDocFP 1391099
        impacts 
          impact 
            freq 9
            norm 95
          impact 
            freq 13
            norm 100
          impact 
            freq 28
            norm 108
        impactsEnd 
  term manager
    doc 0
      freq 11
      pos 5301
      pos 10836
      pos 11376
      pos 12016
      pos 13123
      pos 13225
      pos 13317
      pos 13442
      pos 13528
      pos 13632
      pos 13722
    doc 15
      freq 2
      pos 3446
      pos 3457
  term managing
    doc 0
      freq 1
      pos 375
    doc 10
      freq 1
      pos 1739
    doc 12
      freq 3
      pos 6301
      pos 6394
      pos 6482
    doc 13
      freq 3
      pos 293
      pos 4184
      pos 4708
    doc 17
      freq 1
      pos 1770
  term mandated
    doc 9
      freq 1
      pos 1110
    doc 17
      freq 1
      pos 974
  term mandatory
    doc 0
      freq 4
      pos 14533
      pos 14546
      pos 14747
      pos 14817
    doc 1
      freq 4
      pos 342
      pos 6381
      pos 6404
      pos 6476
    doc 2
      freq 3
      pos 5838
      pos 5866
      pos 5919
    doc 4
      freq 2
      pos 4437
      pos 4541
    doc 10
      freq 2
      pos 3219
      pos 11341
    doc 18
      freq 1
      pos 1759
  term mangles
    doc 12
      freq 1
      pos 6532
  term mankin
    doc 5
      freq 1
      pos 4096
  term manner
    doc 2
      freq 2
      pos 3864
      pos 4148
    doc 9
      freq 1
      pos 292
    doc 10
      freq 4
      pos 1173
      pos 2748
      pos 3984
      pos 4259
    doc 12
      freq 1
      pos 6670
  term manning
    doc 18
      freq 1
      pos 2030
  term mansfield
    doc 6
      freq 1
      pos 3188
  term manual
    doc 0
      freq 9
      pos 3027
      pos 3048
      pos 7484
      pos 10799
      pos 10830
      pos 10855
      pos 11349
      pos 11370
      pos 12842
    doc 2
      freq 1
      pos 647
    doc 6
      freq 1
      pos 2461
    doc 9
      freq 2
      pos 1066
      pos 1413
    doc 12
      freq 8
      pos 359
      pos 383
      pos 4122
      pos 4372
      pos 4436
      pos 4465
      pos 5259
      pos 5272
    doc 15
      freq 3
      pos 1043
      pos 1098
      pos 3093
  term manualaddressesdroppedfromare
    doc 0
      freq 1
      pos 7494
  term manualareaaddresses
    doc 0
      freq 1
      pos 3128
  term manually
    doc 0
      freq 14
      pos 501
      pos 845
      pos 870
      pos 2264
      pos 2448
      pos 3150
      pos 3186
      pos 3501
      pos 5004
      pos 5026
      pos 5106
      pos 9958
      pos 10872
      pos 10908
    doc 2
      freq 1
      pos 1059
    doc 3
      freq 1
      pos 1175
    doc 9
      freq 2
      pos 644
      pos 1086
    doc 10
      freq 1
      pos 736
    doc 12
      freq 3
      pos 3920
      pos 5409
      pos 6929
    doc 13
      freq 1
      pos 2972
    doc 15
      freq 2
      pos 1060
      pos 2197
    skipList 
      level 0
        skipDoc 15
        skipDocFP 1395210
        impacts 
          impact 
            freq 2
            norm 95
          impact 
            freq 3
            norm 113
          impact 
            freq 14
            norm 120
        impactsEnd 
  term manualorautomatic
    doc 0
      freq 17
      pos 2247
      pos 10126
      pos 10187
      pos 10222
      pos 10278
      pos 10492
      pos 10526
      pos 10589
      pos 10699
      pos 10783
      pos 11396
      pos 11425
      pos 11477
      pos 11522
      pos 11552
      pos 11586
      pos 11630
  term many
    doc 3
      freq 1
      pos 3234
    doc 5
      freq 2
      pos 360
      pos 706
    doc 6
      freq 2
      pos 351
      pos 2135
    doc 7
      freq 2
      pos 322
      pos 1687
    doc 9
      freq 1
      pos 1052
    doc 10
      freq 8
      pos 716
      pos 2304
      pos 2792
      pos 3121
      pos 7398
      pos 9656
      pos 9897
      pos 11134
    doc 11
      freq 8
      pos 774
      pos 785
      pos 1384
      pos 2722
      pos 8362
      pos 8580
      pos 9343
      pos 9357
    doc 12
      freq 7
      pos 993
      pos 2762
      pos 5194
      pos 8673
      pos 8798
      pos 9251
      pos 9299
    doc 13
      freq 11
      pos 891
      pos 962
      pos 1054
      pos 1724
      pos 2054
      pos 2778
      pos 3218
      pos 3678
      pos 3795
      pos 5211
      pos 5243
    doc 14
      freq 2
      pos 859
      pos 1534
    doc 15
      freq 2
      pos 1054
      pos 3023
    doc 18
      freq 3
      pos 324
      pos 947
      pos 1997
    skipList 
      level 0
        skipDoc 12
        skipDocFP 1396387
        impacts 
          impact 
            freq 1
            norm 95
          impact 
            freq 2
            norm 100
          impact 
            freq 7
            norm 113
          impact 
            freq 8
            norm 114
        impactsEnd 
  term map
    doc 1
      freq 1
      pos 4527
    doc 3
      freq 3
      pos 1825
      pos 5528
      pos 5552
    doc 5
      freq 1
      pos 1669
    doc 14
      freq 1
      pos 1834
  term mapped
    doc 3
      freq 7
      pos 3925
      pos 3965
      pos 3979
      pos 3995
      pos 5471
      pos 5490
      pos 5520
    doc 4
      freq 1
      pos 2452
    doc 10
      freq 1
      pos 2933
    doc 15
      freq 3
      pos 1570
      pos 2931
      pos 2974
  term mapping
    doc 0
      freq 4
      pos 10253
      pos 10284
      pos 10290
      pos 10336
    doc 1
      freq 44
      pos 2089
      pos 4378
      pos 4387
      pos 4420
      pos 4558
      pos 4582
      pos 4647
      pos 4681
      pos 4703
      pos 4753
      pos 4764
      pos 4818
      pos 4986
      pos 5648
      pos 5765
      pos 5774
      pos 5888
      pos 5953
      pos 6300
      pos 6319
      pos 6500
      pos 6512
      pos 6532
      pos 6540
      pos 6556
      pos 6581
      pos 6596
      pos 6631
      pos 6648
      pos 6663
      pos 6694
      pos 6788
      pos 6801
      pos 6830
      pos 6838
      pos 6853
      pos 6870
      pos 6878
      pos 6905
      pos 6963
      pos 7075
      pos 7471
      pos 9419
      pos 9487
    doc 2
      freq 1
      pos 3915
    doc 3
      freq 4
      pos 4028
      pos 5626
      pos 5780
      pos 5821
    doc 5
      freq 1
      pos 2795
    doc 10
      freq 1
      pos 2844
    doc 12
      freq 3
      pos 1606
      pos 4222
      pos 7853
  term mappings
    doc 1
      freq 2
      pos 297
      pos 4811
    doc 12
      freq 2
      pos 4379
      pos 5988
  term mappingtyp
    doc 0
      freq 1
      pos 10461
  term maps
    doc 1
      freq 1
      pos 4455
    doc 12
      freq 1
      pos 1407
  term marc
    doc 6
      freq 1
      pos 3095
    doc 11
      freq 2
      pos 9449
      pos 9483
  term march
    doc 0
      freq 2
      pos 15845
      pos 16958
    doc 1
      freq 2
      pos 8909
      pos 9163
    doc 2
      freq 28
      pos 15
      pos 201
      pos 630
      pos 1080
      pos 1474
      pos 1849
      pos 2222
      pos 2380
      pos 2459
      pos 2703
      pos 2759
      pos 2952
      pos 2967
      pos 3208
      pos 3302
      pos 3449
      pos 3492
      pos 3875
      pos 4259
      pos 4299
      pos 4667
      pos 5028
      pos 5424
      pos 5793
      pos 5829
      pos 6222
      pos 6336
      pos 6399
    doc 3
      freq 4
      pos 4509
      pos 4530
      pos 4711
      pos 4730
    doc 4
      freq 27
      pos 26
      pos 146
      pos 427
      pos 747
      pos 1016
      pos 1373
      pos 1760
      pos 2082
      pos 2319
      pos 2723
      pos 2969
      pos 3206
      pos 3442
      pos 3632
      pos 3804
      pos 4094
      pos 4504
      pos 4890
      pos 5161
      pos 5284
      pos 5298
      pos 5326
      pos 5406
      pos 5536
      pos 5821
      pos 6040
      pos 6106
    doc 5
      freq 21
      pos 15
      pos 252
      pos 355
      pos 791
      pos 1148
      pos 1479
      pos 1746
      pos 2049
      pos 2360
      pos 2557
      pos 2738
      pos 3052
      pos 3362
      pos 3663
      pos 3915
      pos 4115
      pos 4139
      pos 4299
      pos 4351
      pos 4374
      pos 4436
    doc 7
      freq 11
      pos 18
      pos 204
      pos 591
      pos 955
      pos 1305
      pos 1653
      pos 1827
      pos 2181
      pos 2539
      pos 2894
      pos 2941
    doc 8
      freq 1
      pos 1779
    doc 9
      freq 1
      pos 1682
    doc 10
      freq 1
      pos 13133
    doc 12
      freq 7
      pos 7366
      pos 7542
      pos 7553
      pos 7569
      pos 7822
      pos 7840
      pos 7876
    doc 13
      freq 1
      pos 6752
    doc 14
      freq 1
      pos 5449
    doc 15
      freq 1
      pos 3907
    doc 16
      freq 2
      pos 2533
      pos 2557
    doc 17
      freq 2
      pos 2044
      pos 2142
    doc 18
      freq 4
      pos 2078
      pos 2101
      pos 2124
      pos 2143
    skipList 
      level 0
        skipDoc 8
        skipDocFP 1399655
        impacts 
          impact 
            freq 1
            norm 97
          impact 
            freq 11
            norm 100
          impact 
            freq 21
            norm 104
          impact 
            freq 28
            norm 108
        impactsEnd 
        skipDoc 17
        skipDocFP 1401266
        impacts 
          impact 
            freq 1
            norm 95
          impact 
            freq 2
            norm 98
          impact 
            freq 7
            norm 113
        impactsEnd 
  term margaret
    doc 15
      freq 1
      pos 3855
  term mark
    doc 3
      freq 1
      pos 5828
    doc 5
      freq 1
      pos 4071
    doc 7
      freq 1
      pos 1593
    doc 10
      freq 1
      pos 12117
    doc 12
      freq 1
      pos 6785
    doc 15
      freq 1
      pos 3859
  term marked
    doc 4
      freq 2
      pos 4435
      pos 4539
    doc 7
      freq 1
      pos 102
    doc 16
      freq 1
      pos 1905
    doc 17
      freq 2
      pos 660
      pos 722
  term market
    doc 12
      freq 1
      pos 9432
  term marking
    doc 7
      freq 1
      pos 1894
  term markings
    doc 3
      freq 1
      pos 5475
  term marks
    doc 2
      freq 2
      pos 1457
      pos 2278
  term markup
    doc 11
      freq 4
      pos 740
      pos 795
      pos 812
      pos 836
  term martin
    doc 1
      freq 40
      pos 4
      pos 197
      pos 420
      pos 828
      pos 1057
      pos 1365
      pos 1858
      pos 2218
      pos 2414
      pos 2688
      pos 3047
      pos 3417
      pos 3602
      pos 3899
      pos 4236
      pos 4630
      pos 5010
      pos 5289
      pos 5681
      pos 6016
      pos 6357
      pos 6752
      pos 7190
      pos 7632
      pos 7882
      pos 8230
      pos 8698
      pos 8954
      pos 9013
      pos 9028
      pos 9049
      pos 9072
      pos 9098
      pos 9217
      pos 9324
      pos 9394
      pos 9489
      pos 9506
      pos 9590
      pos 9923
    doc 3
      freq 28
      pos 4
      pos 160
      pos 325
      pos 572
      pos 752
      pos 1031
      pos 1417
      pos 1770
      pos 2109
      pos 2420
      pos 2815
      pos 3199
      pos 3608
      pos 4002
      pos 4290
      pos 4337
      pos 4356
      pos 4551
      pos 4732
      pos 4825
      pos 4929
      pos 4994
      pos 5190
      pos 5580
      pos 5781
      pos 5870
      pos 5937
      pos 6272
    doc 8
      freq 18
      pos 4
      pos 179
      pos 466
      pos 634
      pos 791
      pos 1118
      pos 1432
      pos 1662
      pos 1785
      pos 1904
      pos 1923
      pos 1938
      pos 1961
      pos 1985
      pos 2104
      pos 2130
      pos 2146
      pos 2479
  term maryland
    doc 2
      freq 2
      pos 2867
      pos 5122
    doc 18
      freq 1
      pos 2168
  term masatak
    doc 12
      freq 1
      pos 6782
  term masinter
    doc 11
      freq 1
      pos 9682
    doc 13
      freq 1
      pos 6889
  term mask
    doc 0
      freq 6
      pos 3842
      pos 4053
      pos 4089
      pos 4342
      pos 10626
      pos 11206
    doc 1
      freq 1
      pos 8523
    doc 8
      freq 1
      pos 1583
  term maskalik
    doc 0
      freq 1
      pos 15953
  term masquerad
    doc 17
      freq 1
      pos 1418
  term massachusetts
    doc 1
      freq 2
      pos 9386
      pos 9564
    doc 3
      freq 2
      pos 4772
      pos 5929
    doc 6
      freq 1
      pos 3189
  term massey
    doc 14
      freq 1
      pos 5435
    doc 18
      freq 3
      pos 2066
      pos 2087
      pos 2110
  term massiv
    doc 13
      freq 2
      pos 4014
      pos 4635
  term match
    doc 0
      freq 6
      pos 1566
      pos 4050
      pos 4086
      pos 9025
      pos 9041
      pos 13998
    doc 1
      freq 2
      pos 1706
      pos 6199
    doc 3
      freq 2
      pos 2071
      pos 2088
    doc 10
      freq 1
      pos 4457
    doc 11
      freq 1
      pos 6820
    doc 12
      freq 1
      pos 5058
    doc 13
      freq 1
      pos 3129
    doc 18
      freq 1
      pos 1539
    skipList 
      level 0
        skipDoc 18
        skipDocFP 1405487
        impacts 
          impact 
            freq 1
            norm 97
          impact 
            freq 2
            norm 107
          impact 
            freq 6
            norm 120
        impactsEnd 
  term matches
    doc 0
      freq 2
      pos 10565
      pos 11621
    doc 3
      freq 1
      pos 1759
    doc 10
      freq 1
      pos 5140
    doc 13
      freq 1
      pos 4462
  term matching
    doc 0
      freq 1
      pos 14095
    doc 4
      freq 3
      pos 2291
      pos 3609
      pos 3642
    doc 11
      freq 3
      pos 1786
      pos 1805
      pos 1835
  term material
    doc 2
      freq 1
      pos 960
    doc 5
      freq 3
      pos 1000
      pos 1024
      pos 2874
    doc 10
      freq 3
      pos 1721
      pos 10165
      pos 10555
    doc 12
      freq 4
      pos 4709
      pos 5159
      pos 5833
      pos 7564
    doc 13
      freq 2
      pos 3227
      pos 3614
  term mathematical
    doc 18
      freq 1
      pos 902
  term mathew
    doc 6
      freq 1
      pos 3154
  term mathild
    doc 1
      freq 1
      pos 9372
    doc 3
      freq 1
      pos 4862
  term matt
    doc 11
      freq 1
      pos 9572
    doc 18
      freq 1
      pos 2019
  term matter
    doc 1
      freq 3
      pos 1278
      pos 3558
      pos 4462
    doc 10
      freq 3
      pos 2734
      pos 9159
      pos 9563
    doc 15
      freq 1
      pos 1921
    doc 17
      freq 1
      pos 1045
  term mau
    doc 2
      freq 3
      pos 265
      pos 3667
      pos 3951
  term maus
    doc 2
      freq 1
      pos 3240
  term mawga1udewqfmambaf8wdqyjkozihvcnaqefbqadgyeaddqytswbdmtstq0mt211
    doc 10
      freq 1
      pos 6279
  term max
    doc 0
      freq 212
      pos 2291
      pos 2334
      pos 2387
      pos 2469
      pos 2546
      pos 2615
      pos 2667
      pos 2725
      pos 2772
      pos 2810
      pos 2858
      pos 2951
      pos 2977
      pos 3038
      pos 3137
      pos 3178
      pos 3234
      pos 3355
      pos 3409
      pos 3469
      pos 3524
      pos 3592
      pos 3697
      pos 3720
      pos 3774
      pos 3883
      pos 3926
      pos 3956
      pos 4006
      pos 4100
      pos 4209
      pos 4232
      pos 4286
      pos 4383
      pos 4459
      pos 4480
      pos 4527
      pos 4560
      pos 4586
      pos 4613
      pos 4653
      pos 4673
      pos 4737
      pos 4757
      pos 4826
      pos 4866
      pos 4965
      pos 5030
      pos 5142
      pos 5171
      pos 5201
      pos 5242
      pos 5411
      pos 5434
      pos 5514
      pos 5593
      pos 5626
      pos 5648
      pos 5732
      pos 5791
      pos 5828
      pos 5905
      pos 5956
      pos 6021
      pos 6081
      pos 6135
      pos 6191
      pos 6215
      pos 6277
      pos 6300
      pos 6383
      pos 6403
      pos 6444
      pos 6470
      pos 6504
      pos 6612
      pos 6722
      pos 6783
      pos 6842
      pos 6936
      pos 6983
      pos 7023
      pos 7101
      pos 7158
      pos 7206
      pos 7227
      pos 7288
      pos 7315
      pos 7388
      pos 7421
      pos 7446
      pos 7473
      pos 7503
      pos 7546
      pos 7573
      pos 7617
      pos 7656
      pos 7684
      pos 7717
      pos 7753
      pos 7774
      pos 7845
      pos 7900
      pos 7931
      pos 7968
      pos 8009
      pos 8048
      pos 8089
      pos 8107
      pos 8143
      pos 8180
      pos 8214
      pos 8273
      pos 8302
      pos 8367
      pos 8395
      pos 8442
      pos 8510
      pos 8568
      pos 8626
      pos 8683
      pos 8728
      pos 8770
      pos 8817
      pos 8850
      pos 8915
      pos 8977
      pos 9008
      pos 9053
      pos 9098
      pos 9122
      pos 9148
      pos 9178
      pos 9252
      pos 9292
      pos 9322
      pos 9401
      pos 9449
      pos 9500
      pos 9532
      pos 9600
      pos 9632
      pos 9685
      pos 9714
      pos 9755
      pos 9825
      pos 9857
      pos 9917
      pos 9975
      pos 9999
      pos 10075
      pos 10108
      pos 10157
      pos 10198
      pos 10243
      pos 10470
      pos 10507
      pos 10541
      pos 10617
      pos 10715
      pos 10815
      pos 10889
      pos 10922
      pos 11073
      pos 11106
      pos 11151
      pos 11249
      pos 11280
      pos 11314
      pos 11353
      pos 11405
      pos 11456
      pos 11500
      pos 11533
      pos 11563
      pos 11597
      pos 11673
      pos 11713
      pos 11732
      pos 11801
      pos 11822
      pos 11846
      pos 11866
      pos 11900
      pos 11924
      pos 11946
      pos 11965
      pos 12038
      pos 12071
      pos 12128
      pos 12165
      pos 12197
      pos 12219
      pos 12238
      pos 12261
      pos 12302
      pos 12337
      pos 12361
      pos 12386
      pos 12414
      pos 12439
      pos 12449
      pos 12477
      pos 12503
      pos 12533
      pos 12577
      pos 12604
      pos 12652
      pos 12673
      pos 12728
      pos 12749
      pos 16105
    doc 6
      freq 8
      pos 1520
      pos 1563
      pos 1891
      pos 1898
      pos 1920
      pos 2198
      pos 2362
      pos 2720
    doc 10
      freq 5
      pos 6350
      pos 6635
      pos 6985
      pos 7122
      pos 7335
    doc 11
      freq 55
      pos 473
      pos 1165
      pos 1180
      pos 1342
      pos 1469
      pos 1990
      pos 2213
      pos 2373
      pos 2588
      pos 2688
      pos 3148
      pos 3341
      pos 3376
      pos 3523
      pos 3626
      pos 3791
      pos 4284
      pos 4452
      pos 4668
      pos 4768
      pos 4811
      pos 4927
      pos 5167
      pos 5325
      pos 5470
      pos 5623
      pos 5820
      pos 5944
      pos 6166
      pos 6356
      pos 6448
      pos 6609
      pos 6685
      pos 6776
      pos 6868
      pos 7113
      pos 7389
      pos 7520
      pos 7657
      pos 7746
      pos 7863
      pos 8050
      pos 8093
      pos 8138
      pos 8181
      pos 8346
      pos 8548
      pos 8560
      pos 8591
      pos 8628
      pos 8737
      pos 8827
      pos 8926
      pos 9081
      pos 9237
    doc 17
      freq 4
      pos 790
      pos 801
      pos 2298
      pos 2309
  term maximiz
    doc 10
      freq 1
      pos 1623
  term maximum
    doc 0
      freq 9
      pos 1626
      pos 2476
      pos 2553
      pos 2886
      pos 3072
      pos 4765
      pos 6849
      pos 7532
      pos 13209
    doc 1
      freq 1
      pos 6152
    doc 3
      freq 2
      pos 1596
      pos 4194
    doc 4
      freq 2
      pos 2848
      pos 3368
    doc 6
      freq 3
      pos 1169
      pos 1315
      pos 2646
    doc 8
      freq 1
      pos 1021
    doc 10
      freq 1
      pos 3170
    doc 14
      freq 43
      pos 197
      pos 520
      pos 529
      pos 660
      pos 664
      pos 717
      pos 725
      pos 734
      pos 865
      pos 891
      pos 898
      pos 922
      pos 957
      pos 976
      pos 1021
      pos 1055
      pos 1094
      pos 1143
      pos 1155
      pos 1354
      pos 1376
      pos 1540
      pos 1628
      pos 1673
      pos 1707
      pos 1735
      pos 1745
      pos 2039
      pos 2199
      pos 2351
      pos 2404
      pos 2492
      pos 3869
      pos 4170
      pos 4236
      pos 4301
      pos 4314
      pos 4423
      pos 4444
      pos 4517
      pos 4599
      pos 5047
      pos 5171
    doc 17
      freq 1
      pos 1211
    doc 18
      freq 1
      pos 1348
    skipList 
      level 0
        skipDoc 14
        skipDocFP 1412172
        impacts 
          impact 
            freq 1
            norm 97
          impact 
            freq 3
            norm 101
          impact 
            freq 43
            norm 107
        impactsEnd 
  term maximumlspgenerationinterval
    doc 0
      freq 1
      pos 2600
  term maximumpathsplits
    doc 0
      freq 1
      pos 2519
  term maximums
    doc 6
      freq 2
      pos 1067
      pos 1112
  term may
    doc 0
      freq 42
      pos 967
      pos 2043
      pos 2078
      pos 2230
      pos 2351
      pos 2429
      pos 2441
      pos 2494
      pos 3550
      pos 4781
      pos 4928
      pos 5000
      pos 5386
      pos 10555
      pos 10599
      pos 10946
      pos 11611
      pos 11996
      pos 12017
      pos 12622
      pos 12963
      pos 13119
      pos 13221
      pos 13313
      pos 13361
      pos 13438
      pos 13524
      pos 13628
      pos 13718
      pos 14099
      pos 14128
      pos 15985
      pos 15997
      pos 16041
      pos 16059
      pos 16117
      pos 16299
      pos 16431
      pos 16447
      pos 17012
      pos 17504
      pos 17508
    doc 1
      freq 24
      pos 535
      pos 900
      pos 1172
      pos 1338
      pos 1713
      pos 1787
      pos 1884
      pos 2005
      pos 2395
      pos 2832
      pos 3222
      pos 3269
      pos 4250
      pos 4343
      pos 4351
      pos 4683
      pos 4873
      pos 8576
      pos 8731
      pos 8767
      pos 8776
      pos 8833
      pos 9885
      pos 9889
    doc 2
      freq 9
      pos 1266
      pos 2047
      pos 2782
      pos 4156
      pos 5401
      pos 5501
      pos 5972
      pos 6682
      pos 6686
    doc 3
      freq 36
      pos 992
      pos 1022
      pos 1190
      pos 1224
      pos 1247
      pos 1453
      pos 1625
      pos 1633
      pos 1666
      pos 2636
      pos 2648
      pos 2658
      pos 2711
      pos 2717
      pos 2723
      pos 2743
      pos 2745
      pos 3029
      pos 3362
      pos 3446
      pos 3480
      pos 3492
      pos 3506
      pos 3592
      pos 3788
      pos 3832
      pos 3923
      pos 3939
      pos 4056
      pos 4242
      pos 5164
      pos 5224
      pos 5364
      pos 5404
      pos 6234
      pos 6238
    doc 4
      freq 18
      pos 363
      pos 456
      pos 1226
      pos 1852
      pos 2657
      pos 3616
      pos 3649
      pos 3705
      pos 3984
      pos 4101
      pos 4133
      pos 4181
      pos 4324
      pos 4354
      pos 4693
      pos 5852
      pos 6389
      pos 6393
    doc 5
      freq 11
      pos 217
      pos 432
      pos 702
      pos 854
      pos 915
      pos 1060
      pos 1897
      pos 2483
      pos 2531
      pos 4719
      pos 4723
    doc 6
      freq 19
      pos 255
      pos 497
      pos 604
      pos 676
      pos 809
      pos 1028
      pos 1084
      pos 1115
      pos 1490
      pos 1529
      pos 2071
      pos 2386
      pos 2417
      pos 2443
      pos 2739
      pos 2794
      pos 2849
      pos 3519
      pos 3523
    doc 7
      freq 5
      pos 1275
      pos 1666
      pos 1738
      pos 3224
      pos 3228
    doc 8
      freq 4
      pos 320
      pos 1701
      pos 2441
      pos 2445
    doc 9
      freq 7
      pos 95
      pos 357
      pos 683
      pos 860
      pos 1018
      pos 2086
      pos 2090
    doc 10
      freq 39
      pos 538
      pos 690
      pos 728
      pos 733
      pos 761
      pos 1658
      pos 1709
      pos 1725
      pos 1882
      pos 1888
      pos 2073
      pos 2585
      pos 3052
      pos 3072
      pos 3131
      pos 3514
      pos 3819
      pos 4681
      pos 4698
      pos 4731
      pos 5022
      pos 5751
      pos 6137
      pos 7694
      pos 7728
      pos 7745
      pos 8089
      pos 10444
      pos 10467
      pos 10504
      pos 10515
      pos 11996
      pos 12080
      pos 12356
      pos 13272
      pos 13282
      pos 13401
      pos 13747
      pos 13751
    doc 11
      freq 64
      pos 29
      pos 195
      pos 498
      pos 825
      pos 1051
      pos 1258
      pos 1444
      pos 1578
      pos 1902
      pos 2116
      pos 2296
      pos 2548
      pos 2789
      pos 3057
      pos 3324
      pos 3447
      pos 3692
      pos 3888
      pos 3938
      pos 3989
      pos 4175
      pos 4415
      pos 4658
      pos 4862
      pos 4896
      pos 5074
      pos 5241
      pos 5286
      pos 5398
      pos 5546
      pos 5586
      pos 5706
      pos 5752
      pos 5838
      pos 6026
      pos 6250
      pos 6427
      pos 6486
      pos 6536
      pos 6722
      pos 6936
      pos 7146
      pos 7274
      pos 7552
      pos 7786
      pos 8033
      pos 8230
      pos 8462
      pos 8646
      pos 8865
      pos 8964
      pos 8998
      pos 9209
      pos 9419
      pos 9726
      pos 9773
      pos 9864
      pos 10030
      pos 10220
      pos 10429
      pos 10522
      pos 10625
      pos 10908
      pos 10912
    doc 12
      freq 33
      pos 329
      pos 1494
      pos 1525
      pos 2447
      pos 2769
      pos 2916
      pos 3250
      pos 3279
      pos 3305
      pos 3510
      pos 3594
      pos 3621
      pos 3800
      pos 3842
      pos 3851
      pos 4929
      pos 5151
      pos 5625
      pos 5873
      pos 5979
      pos 6391
      pos 6656
      pos 6931
      pos 6967
      pos 7384
      pos 7525
      pos 8037
      pos 8509
      pos 8547
      pos 8829
      pos 8837
      pos 9758
      pos 9762
    doc 13
      freq 86
      pos 29
      pos 130
      pos 360
      pos 632
      pos 672
      pos 693
      pos 764
      pos 769
      pos 800
      pos 812
      pos 829
      pos 839
      pos 876
      pos 889
      pos 978
      pos 1146
      pos 1196
      pos 1303
      pos 1386
      pos 1467
      pos 1826
      pos 2178
      pos 2196
      pos 2268
      pos 2512
      pos 2544
      pos 2570
      pos 2599
      pos 2629
      pos 2643
      pos 2707
      pos 2781
      pos 2857
      pos 2941
      pos 3009
      pos 3085
      pos 3099
      pos 3130
      pos 3308
      pos 3510
      pos 3669
      pos 3751
      pos 3895
      pos 3923
      pos 3970
      pos 4262
      pos 4305
      pos 4340
      pos 4390
      pos 4563
      pos 4665
      pos 4680
      pos 4843
      pos 4904
      pos 4931
      pos 5008
      pos 5025
      pos 5112
      pos 5286
      pos 5345
      pos 5387
      pos 5683
      pos 5716
      pos 5737
      pos 6016
      pos 6032
      pos 6044
      pos 6143
      pos 6153
      pos 6169
      pos 6182
      pos 6195
      pos 6338
      pos 6344
      pos 6371
      pos 6389
      pos 6467
      pos 6503
      pos 6528
      pos 6573
      pos 6660
      pos 6688
      pos 6950
      pos 7090
      pos 7373
      pos 7377
    doc 14
      freq 14
      pos 88
      pos 2032
      pos 2091
      pos 2183
      pos 2234
      pos 2263
      pos 2408
      pos 2443
      pos 2679
      pos 2803
      pos 2874
      pos 5300
      pos 5839
      pos 5843
    doc 15
      freq 80
      pos 23
      pos 75
      pos 89
      pos 198
      pos 309
      pos 388
      pos 403
      pos 639
      pos 663
      pos 850
      pos 871
      pos 886
      pos 939
      pos 945
      pos 1029
      pos 1033
      pos 1067
      pos 1094
      pos 1114
      pos 1144
      pos 1155
      pos 1169
      pos 1207
      pos 1256
      pos 1318
      pos 1345
      pos 1358
      pos 1397
      pos 1475
      pos 1504
      pos 1560
      pos 1565
      pos 1589
      pos 1619
      pos 1634
      pos 1639
      pos 1725
      pos 1757
      pos 1839
      pos 1841
      pos 1907
      pos 1919
      pos 1969
      pos 2021
      pos 2046
      pos 2106
      pos 2127
      pos 2152
      pos 2166
      pos 2281
      pos 2294
      pos 2342
      pos 2477
      pos 2598
      pos 2684
      pos 2905
      pos 3010
      pos 3070
      pos 3087
      pos 3134
      pos 3172
      pos 3193
      pos 3198
      pos 3257
      pos 3262
      pos 3293
      pos 3295
      pos 3411
      pos 3586
      pos 3632
      pos 3641
      pos 3673
      pos 3749
      pos 3766
      pos 3806
      pos 3866
      pos 4012
      pos 4075
      pos 4358
      pos 4362
    doc 16
      freq 5
      pos 112
      pos 1235
      pos 1389
      pos 2969
      pos 2973
    doc 17
      freq 29
      pos 16
      pos 160
      pos 210
      pos 280
      pos 341
      pos 390
      pos 424
      pos 441
      pos 519
      pos 571
      pos 653
      pos 819
      pos 969
      pos 1057
      pos 1176
      pos 1326
      pos 1341
      pos 1403
      pos 1500
      pos 1604
      pos 1830
      pos 1852
      pos 1880
      pos 2117
      pos 2155
      pos 2324
      pos 2410
      pos 2693
      pos 2697
    doc 18
      freq 13
      pos 395
      pos 420
      pos 563
      pos 923
      pos 957
      pos 1071
      pos 1190
      pos 1677
      pos 1722
      pos 1832
      pos 1882
      pos 2481
      pos 2485
    skipList 
      level 0
        skipDoc 7
        skipDocFP 1413855
        impacts 
          impact 
            freq 5
            norm 100
          impact 
            freq 19
            norm 101
          impact 
            freq 36
            norm 107
          impact 
            freq 42
            norm 120
        impactsEnd 
        skipDoc 15
        skipDocFP 1416518
        impacts 
          impact 
            freq 7
            norm 95
          impact 
            freq 80
            norm 104
          impact 
            freq 86
            norm 109
        impactsEnd 
  term maybe
    doc 12
      freq 1
      pos 5044
  term mazu
    doc 1
      freq 1
      pos 9188
  term mazunetworks.com
    doc 1
      freq 1
      pos 9199
  term mb
    doc 6
      freq 4
      pos 1237
      pos 1249
      pos 1392
      pos 1443
  term mbomusxw9tbz7pykaigbx7u7kne6ivfk6h9rlxhoaaz1
    doc 11
      freq 1
      pos 10318
  term mbone
    doc 13
      freq 1
      pos 402
  term mccann
    doc 4
      freq 1
      pos 5347
  term mccloghr
    doc 0
      freq 4
      pos 16981
      pos 17040
      pos 17061
      pos 17079
    doc 2
      freq 6
      pos 2905
      pos 2926
      pos 2996
      pos 3570
      pos 3586
      pos 4281
  term mcgrew
    doc 5
      freq 1
      pos 4356
  term mci
    doc 11
      freq 2
      pos 9578
      pos 9610
  term mckinnon
    doc 11
      freq 1
      pos 9593
  term mcl01
    doc 11
      freq 2
      pos 8314
      pos 8338
  term mcmaster
    doc 2
      freq 1
      pos 2922
  term mcpherson
    doc 0
      freq 1
      pos 15949
    doc 3
      freq 2
      pos 4317
      pos 4571
    doc 8
      freq 1
      pos 2108
  term mcqhh
    doc 10
      freq 1
      pos 12786
  term md5
    doc 1
      freq 3
      pos 8624
      pos 8670
      pos 8690
    doc 7
      freq 2
      pos 1101
      pos 2723
  term mdcq8u
    doc 11
      freq 1
      pos 10135
  term mdi
    doc 6
      freq 33
      pos 24
      pos 183
      pos 254
      pos 271
      pos 294
      pos 541
      pos 653
      pos 668
      pos 747
      pos 788
      pos 891
      pos 915
      pos 1007
      pos 1038
      pos 1072
      pos 1137
      pos 1146
      pos 1618
      pos 2033
      pos 2171
      pos 2238
      pos 2267
      pos 2347
      pos 2353
      pos 2454
      pos 2468
      pos 2570
      pos 2618
      pos 2688
      pos 2763
      pos 3040
      pos 3177
      pos 3230
  term mdi0mdyznja2wjbzmqswcqydvqqgewjvuzelmakga1uecawcr0exedaobgnvbacm
    doc 10
      freq 1
      pos 6251
  term mdnsent
    doc 16
      freq 4
      pos 1778
      pos 1939
      pos 2159
      pos 2307
  term me
    doc 10
      freq 1
      pos 12505
  term mealling
    doc 10
      freq 1
      pos 13342
  term mean
    doc 11
      freq 1
      pos 2044
    doc 12
      freq 2
      pos 844
      pos 2631
    doc 15
      freq 1
      pos 2741
  term meaning
    doc 1
      freq 1
      pos 2113
    doc 5
      freq 1
      pos 1902
    doc 11
      freq 1
      pos 993
    doc 14
      freq 1
      pos 2343
  term meaningful
    doc 3
      freq 4
      pos 1152
      pos 1204
      pos 2462
      pos 2689
    doc 11
      freq 1
      pos 7459
  term meaningfully
    doc 15
      freq 1
      pos 2704
  term meaningless
    doc 10
      freq 1
      pos 7974
  term meanings
    doc 0
      freq 1
      pos 1468
  term means
    doc 0
      freq 1
      pos 6097
    doc 1
      freq 4
      pos 4613
      pos 4880
      pos 8070
      pos 8582
    doc 3
      freq 3
      pos 2356
      pos 2444
      pos 3945
    doc 4
      freq 1
      pos 2592
    doc 8
      freq 1
      pos 965
    doc 10
      freq 6
      pos 895
      pos 1012
      pos 1535
      pos 3660
      pos 3944
      pos 4362
    doc 12
      freq 2
      pos 613
      pos 5849
    doc 13
      freq 2
      pos 439
      pos 1613
    doc 17
      freq 4
      pos 1811
      pos 1890
      pos 1919
      pos 1924
    skipList 
      level 0
        skipDoc 13
        skipDocFP 1425761
        impacts 
          impact 
            freq 1
            norm 97
          impact 
            freq 3
            norm 107
          impact 
            freq 4
            norm 113
          impact 
            freq 6
            norm 116
        impactsEnd 
  term meant
    doc 2
      freq 1
      pos 4539
    doc 11
      freq 1
      pos 2524
    doc 12
      freq 3
      pos 521
      pos 569
      pos 4118
  term meantim
    doc 9
      freq 1
      pos 1500
  term measur
    doc 6
      freq 4
      pos 232
      pos 246
      pos 899
      pos 1496
  term measured
    doc 0
      freq 2
      pos 6149
      pos 9338
    doc 6
      freq 1
      pos 2268
  term measurement
    doc 6
      freq 21
      pos 184
      pos 272
      pos 626
      pos 656
      pos 820
      pos 1079
      pos 1082
      pos 1121
      pos 1525
      pos 1551
      pos 1826
      pos 1829
      pos 1872
      pos 1911
      pos 1928
      pos 1990
      pos 1996
      pos 2000
      pos 2322
      pos 2368
      pos 2724
  term measurements
    doc 6
      freq 6
      pos 530
      pos 2571
      pos 2770
      pos 2792
      pos 2817
      pos 2855
  term measures
    doc 1
      freq 1
      pos 8209
    doc 9
      freq 1
      pos 1109
    doc 17
      freq 1
      pos 1474
  term mechanics
    doc 10
      freq 1
      pos 9771
  term mechanism
    doc 1
      freq 1
      pos 2078
    doc 2
      freq 1
      pos 1564
    doc 3
      freq 3
      pos 3155
      pos 3351
      pos 5315
    doc 4
      freq 3
      pos 4171
      pos 4392
      pos 5596
    doc 7
      freq 2
      pos 2831
      pos 2871
    doc 9
      freq 15
      pos 160
      pos 174
      pos 211
      pos 240
      pos 314
      pos 386
      pos 455
      pos 498
      pos 500
      pos 532
      pos 616
      pos 1272
      pos 1527
      pos 1543
      pos 1556
    doc 10
      freq 44
      pos 125
      pos 510
      pos 856
      pos 1477
      pos 1761
      pos 3482
      pos 4315
      pos 4344
      pos 4372
      pos 4396
      pos 5156
      pos 5851
      pos 5902
      pos 6086
      pos 7430
      pos 7529
      pos 7771
      pos 8190
      pos 8218
      pos 9051
      pos 9069
      pos 9167
      pos 9196
      pos 9278
      pos 9383
      pos 9465
      pos 9526
      pos 9537
      pos 10007
      pos 10021
      pos 10080
      pos 10172
      pos 10174
      pos 10197
      pos 10252
      pos 10303
      pos 10856
      pos 11328
      pos 12851
      pos 12865
      pos 12963
      pos 12981
      pos 13001
      pos 13140
    doc 11
      freq 4
      pos 155
      pos 2008
      pos 2016
      pos 3579
    doc 12
      freq 7
      pos 1368
      pos 1405
      pos 1513
      pos 1581
      pos 4419
      pos 6909
      pos 8334
    doc 13
      freq 8
      pos 1121
      pos 1658
      pos 1746
      pos 3773
      pos 4468
      pos 5617
      pos 6624
      pos 6727
    doc 16
      freq 1
      pos 473
    doc 18
      freq 3
      pos 524
      pos 541
      pos 575
    skipList 
      level 0
        skipDoc 11
        skipDocFP 1427769
        impacts 
          impact 
            freq 15
            norm 95
          impact 
            freq 44
            norm 116
        impactsEnd 
  term mechanisms
    doc 0
      freq 2
      pos 258
      pos 16742
    doc 1
      freq 2
      pos 1939
      pos 1960
    doc 3
      freq 4
      pos 826
      pos 1582
      pos 3088
      pos 3311
    doc 4
      freq 1
      pos 1945
    doc 5
      freq 3
      pos 192
      pos 3007
      pos 3259
    doc 7
      freq 1
      pos 2603
    doc 9
      freq 1
      pos 304
    doc 10
      freq 7
      pos 94
      pos 411
      pos 518
      pos 1789
      pos 9744
      pos 9928
      pos 9992
    doc 11
      freq 2
      pos 7689
      pos 9708
    doc 12
      freq 12
      pos 208
      pos 1502
      pos 1519
      pos 4014
      pos 4054
      pos 4457
      pos 5110
      pos 5205
      pos 6973
      pos 7090
      pos 7579
      pos 9324
    doc 13
      freq 13
      pos 1036
      pos 1080
      pos 1102
      pos 1155
      pos 1576
      pos 1978
      pos 3675
      pos 3826
      pos 3941
      pos 3955
      pos 3997
      pos 5086
      pos 6634
    doc 14
      freq 1
      pos 5499
    doc 16
      freq 1
      pos 405
    doc 17
      freq 6
      pos 537
      pos 874
      pos 899
      pos 2181
      pos 2221
      pos 2246
    skipList 
      level 0
        skipDoc 10
        skipDocFP 1429675
        impacts 
          impact 
            freq 1
            norm 95
          impact 
            freq 3
            norm 104
          impact 
            freq 4
            norm 107
          impact 
            freq 7
            norm 116
        impactsEnd 
  term medford
    doc 6
      freq 1
      pos 3140
  term media
    doc 2
      freq 1
      pos 2543
    doc 5
      freq 6
      pos 985
      pos 1974
      pos 2489
      pos 2516
      pos 2748
      pos 2840
    doc 6
      freq 40
      pos 21
      pos 180
      pos 208
      pos 269
      pos 291
      pos 331
      pos 444
      pos 538
      pos 554
      pos 583
      pos 744
      pos 814
      pos 910
      pos 944
      pos 1055
      pos 1134
      pos 1141
      pos 1157
      pos 1177
      pos 1184
      pos 1190
      pos 1218
      pos 1230
      pos 1297
      pos 1329
      pos 1615
      pos 1755
      pos 1780
      pos 2030
      pos 2037
      pos 2041
      pos 2153
      pos 2161
      pos 2182
      pos 2344
      pos 2701
      pos 2749
      pos 2760
      pos 3037
      pos 3227
    doc 7
      freq 2
      pos 1010
      pos 2497
    doc 10
      freq 2
      pos 9127
      pos 13016
    doc 11
      freq 1
      pos 7840
    doc 13
      freq 51
      pos 34
      pos 88
      pos 93
      pos 127
      pos 210
      pos 357
      pos 510
      pos 571
      pos 592
      pos 761
      pos 837
      pos 1034
      pos 1143
      pos 1216
      pos 1296
      pos 1464
      pos 1552
      pos 1571
      pos 1633
      pos 1823
      pos 2051
      pos 2175
      pos 2567
      pos 2668
      pos 2676
      pos 2749
      pos 2938
      pos 3053
      pos 3060
      pos 3150
      pos 3185
      pos 3219
      pos 3305
      pos 3666
      pos 3967
      pos 4302
      pos 4407
      pos 4677
      pos 4988
      pos 5022
      pos 5384
      pos 5654
      pos 5734
      pos 6013
      pos 6180
      pos 6193
      pos 6335
      pos 6657
      pos 6873
      pos 6947
      pos 7087
  term media's
    doc 13
      freq 1
      pos 4998
  term mediated
    doc 10
      freq 1
      pos 1259
  term medium
    doc 2
      freq 4
      pos 2642
      pos 2676
      pos 2731
      pos 3237
    doc 13
      freq 1
      pos 2526
  term meet
    doc 4
      freq 1
      pos 1586
    doc 10
      freq 2
      pos 3084
      pos 10527
    doc 11
      freq 1
      pos 746
    doc 12
      freq 1
      pos 8219
    doc 13
      freq 1
      pos 4695
  term meeting
    doc 2
      freq 5
      pos 382
      pos 4295
      pos 4302
      pos 5449
      pos 5851
  term meetings
    doc 2
      freq 3
      pos 931
      pos 1195
      pos 5665
  term melnikov
    doc 16
      freq 2
      pos 1593
      pos 2622
  term member
    doc 0
      freq 1
      pos 5967
  term members
    doc 1
      freq 2
      pos 3215
      pos 3228
    doc 2
      freq 5
      pos 183
      pos 346
      pos 4508
      pos 5677
      pos 6341
    doc 5
      freq 1
      pos 426
    doc 7
      freq 3
      pos 225
      pos 545
      pos 1777
    doc 16
      freq 1
      pos 1580
  term membership
    doc 2
      freq 2
      pos 870
      pos 881
  term memo
    doc 0
      freq 4
      pos 31
      pos 77
      pos 90
      pos 268
    doc 1
      freq 2
      pos 48
      pos 94
    doc 2
      freq 3
      pos 25
      pos 27
      pos 47
    doc 3
      freq 2
      pos 42
      pos 88
    doc 4
      freq 2
      pos 44
      pos 90
    doc 5
      freq 2
      pos 28
      pos 74
    doc 6
      freq 7
      pos 28
      pos 30
      pos 50
      pos 177
      pos 276
      pos 523
      pos 561
    doc 7
      freq 4
      pos 39
      pos 41
      pos 61
      pos 74
    doc 8
      freq 2
      pos 32
      pos 55
    doc 9
      freq 2
      pos 30
      pos 76
    doc 10
      freq 2
      pos 33
      pos 79
    doc 11
      freq 3
      pos 41
      pos 43
      pos 63
    doc 12
      freq 9
      pos 31
      pos 33
      pos 53
      pos 66
      pos 124
      pos 510
      pos 730
      pos 4333
      pos 4406
    doc 13
      freq 4
      pos 40
      pos 42
      pos 62
      pos 75
    doc 14
      freq 3
      pos 26
      pos 28
      pos 57
    doc 15
      freq 3
      pos 39
      pos 41
      pos 61
    doc 16
      freq 2
      pos 29
      pos 75
    doc 17
      freq 2
      pos 26
      pos 72
    doc 18
      freq 2
      pos 35
      pos 81
    skipList 
      level 0
        skipDoc 7
        skipDocFP 1434093
        impacts 
          impact 
            freq 4
            norm 100
          impact 
            freq 7
            norm 101
        impactsEnd 
        skipDoc 15
        skipDocFP 1434620
        impacts 
          impact 
            freq 2
            norm 95
          impact 
            freq 3
            norm 104
          impact 
            freq 4
            norm 109
          impact 
            freq 9
            norm 113
        impactsEnd 
  term memory
    doc 0
      freq 7
      pos 4925
      pos 4994
      pos 5100
      pos 5134
      pos 7313
      pos 7326
      pos 12941
    doc 12
      freq 1
      pos 6620
  term men
    doc 10
      freq 2
      pos 9286
      pos 9454
  term mention
    doc 7
      freq 1
      pos 1430
  term mentioned
    doc 1
      freq 3
      pos 5441
      pos 7096
      pos 8130
    doc 5
      freq 2
      pos 852
      pos 1487
    doc 6
      freq 1
      pos 1852
    doc 12
      freq 3
      pos 1505
      pos 1664
      pos 8222
  term mentions
    doc 2
      freq 1
      pos 3782
  term mercer
    doc 6
      freq 1
      pos 3150
  term merchantability
    doc 0
      freq 1
      pos 17325
    doc 1
      freq 1
      pos 9706
    doc 2
      freq 1
      pos 6503
    doc 3
      freq 1
      pos 6055
    doc 4
      freq 1
      pos 6210
    doc 5
      freq 1
      pos 4540
    doc 6
      freq 1
      pos 3340
    doc 7
      freq 1
      pos 3045
    doc 8
      freq 1
      pos 2262
    doc 9
      freq 1
      pos 1907
    doc 10
      freq 1
      pos 13568
    doc 11
      freq 1
      pos 10729
    doc 12
      freq 1
      pos 9579
    doc 13
      freq 1
      pos 7194
    doc 14
      freq 1
      pos 5660
    doc 15
      freq 1
      pos 4179
    doc 16
      freq 1
      pos 2790
    doc 17
      freq 1
      pos 2514
    doc 18
      freq 1
      pos 2302
    skipList 
      level 0
        skipDoc 7
        skipDocFP 1436542
        impacts 
          impact 
            freq 1
            norm 100
        impactsEnd 
        skipDoc 15
        skipDocFP 1436847
        impacts 
          impact 
            freq 1
            norm 95
        impactsEnd 
  term merely
    doc 10
      freq 1
      pos 8915
  term merge
    doc 13
      freq 1
      pos 1392
    doc 15
      freq 1
      pos 1467
  term merged
    doc 15
      freq 1
      pos 1896
  term merger
    doc 15
      freq 3
      pos 917
      pos 2039
      pos 3707
  term merging
    doc 15
      freq 8
      pos 929
      pos 963
      pos 1008
      pos 1789
      pos 2913
      pos 3045
      pos 3534
      pos 3701
  term merits
    doc 15
      freq 1
      pos 1577
  term mesh
    doc 0
      freq 10
      pos 433
      pos 5970
      pos 5980
      pos 5995
      pos 6007
      pos 6032
      pos 6047
      pos 6059
      pos 16547
      pos 17141
    doc 7
      freq 2
      pos 1131
      pos 2790
  term messag
    doc 1
      freq 77
      pos 2090
      pos 2294
      pos 2329
      pos 4379
      pos 4388
      pos 4421
      pos 4425
      pos 4541
      pos 4559
      pos 4570
      pos 4648
      pos 4682
      pos 4704
      pos 4754
      pos 4765
      pos 4951
      pos 4987
      pos 5055
      pos 5171
      pos 5224
      pos 5231
      pos 5272
      pos 5274
      pos 5329
      pos 5331
      pos 5334
      pos 5362
      pos 5376
      pos 5387
      pos 5412
      pos 5491
      pos 5595
      pos 5649
      pos 5766
      pos 5775
      pos 5889
      pos 5954
      pos 5965
      pos 6320
      pos 6337
      pos 6501
      pos 6513
      pos 6533
      pos 6541
      pos 6557
      pos 6582
      pos 6597
      pos 6632
      pos 6649
      pos 6664
      pos 6695
      pos 6773
      pos 6789
      pos 6802
      pos 6831
      pos 6839
      pos 6854
      pos 6863
      pos 6871
      pos 6879
      pos 6893
      pos 6906
      pos 6927
      pos 6952
      pos 6964
      pos 7076
      pos 7147
      pos 7275
      pos 7330
      pos 7336
      pos 7350
      pos 7472
      pos 7700
      pos 7711
      pos 7727
      pos 9481
      pos 9488
    doc 3
      freq 3
      pos 1564
      pos 1810
      pos 1890
    doc 4
      freq 109
      pos 30
      pos 118
      pos 125
      pos 161
      pos 166
      pos 172
      pos 177
      pos 189
      pos 195
      pos 200
      pos 205
      pos 215
      pos 220
      pos 292
      pos 368
      pos 530
      pos 535
      pos 625
      pos 635
      pos 651
      pos 662
      pos 676
      pos 711
      pos 719
      pos 728
      pos 753
      pos 973
      pos 985
      pos 991
      pos 998
      pos 1044
      pos 1058
      pos 1068
      pos 1104
      pos 1110
      pos 1116
      pos 1139
      pos 1145
      pos 1253
      pos 1273
      pos 1278
      pos 1344
      pos 1380
      pos 1420
      pos 1435
      pos 1460
      pos 1483
      pos 1508
      pos 1539
      pos 1542
      pos 1560
      pos 1598
      pos 1634
      pos 1651
      pos 1657
      pos 1682
      pos 1700
      pos 1812
      pos 1967
      pos 2062
      pos 2091
      pos 2230
      pos 2266
      pos 2499
      pos 2566
      pos 2735
      pos 2757
      pos 2892
      pos 2909
      pos 2926
      pos 2979
      pos 3002
      pos 3148
      pos 3176
      pos 3215
      pos 3238
      pos 3374
      pos 3416
      pos 3474
      pos 3520
      pos 3545
      pos 3716
      pos 3790
      pos 3816
      pos 3825
      pos 3880
      pos 3893
      pos 3906
      pos 3938
      pos 3949
      pos 3961
      pos 3979
      pos 3983
      pos 3996
      pos 4146
      pos 4156
      pos 4177
      pos 4190
      pos 4206
      pos 4331
      pos 4346
      pos 4460
      pos 4619
      pos 5218
      pos 5235
      pos 5639
      pos 5736
      pos 5784
      pos 5989
    doc 5
      freq 13
      pos 145
      pos 235
      pos 375
      pos 404
      pos 2283
      pos 2326
      pos 2335
      pos 2367
      pos 2390
      pos 2399
      pos 2419
      pos 2599
      pos 3502
    doc 7
      freq 5
      pos 804
      pos 921
      pos 2214
      pos 2385
      pos 2858
    doc 10
      freq 56
      pos 1295
      pos 1923
      pos 1948
      pos 2307
      pos 2317
      pos 2560
      pos 2788
      pos 3386
      pos 3813
      pos 3832
      pos 3908
      pos 4008
      pos 4225
      pos 4709
      pos 4787
      pos 4886
      pos 4916
      pos 5209
      pos 5219
      pos 5226
      pos 5234
      pos 5239
      pos 5252
      pos 5264
      pos 5269
      pos 5339
      pos 5717
      pos 6006
      pos 6601
      pos 6800
      pos 7106
      pos 7189
      pos 7317
      pos 7998
      pos 8087
      pos 8305
      pos 8358
      pos 8526
      pos 8768
      pos 9222
      pos 9245
      pos 9721
      pos 9894
      pos 10155
      pos 11394
      pos 11872
      pos 12219
      pos 12222
      pos 12232
      pos 12285
      pos 12404
      pos 12407
      pos 12451
      pos 12823
      pos 13011
      pos 13204
    doc 11
      freq 110
      pos 174
      pos 232
      pos 259
      pos 550
      pos 677
      pos 762
      pos 1003
      pos 1209
      pos 1446
      pos 1587
      pos 1904
      pos 2127
      pos 2132
      pos 2191
      pos 2315
      pos 2323
      pos 2354
      pos 2423
      pos 2482
      pos 2506
      pos 2517
      pos 2532
      pos 2550
      pos 2607
      pos 2671
      pos 2791
      pos 3211
      pos 3326
      pos 3488
      pos 3504
      pos 3543
      pos 3545
      pos 3584
      pos 3591
      pos 3610
      pos 3697
      pos 3699
      pos 3724
      pos 3730
      pos 3768
      pos 3771
      pos 3828
      pos 3976
      pos 3991
      pos 4095
      pos 4111
      pos 4124
      pos 4251
      pos 4268
      pos 4348
      pos 4353
      pos 4374
      pos 4390
      pos 4444
      pos 4541
      pos 4660
      pos 4898
      pos 5017
      pos 5123
      pos 5148
      pos 5309
      pos 5449
      pos 5615
      pos 5781
      pos 5925
      pos 6150
      pos 6341
      pos 6431
      pos 6588
      pos 6593
      pos 6670
      pos 6760
      pos 6803
      pos 6852
      pos 6960
      pos 7054
      pos 7097
      pos 7185
      pos 7204
      pos 7374
      pos 7503
      pos 7562
      pos 7578
      pos 7589
      pos 7594
      pos 7633
      pos 7730
      pos 7843
      pos 8035
      pos 8083
      pos 8119
      pos 8271
      pos 8312
      pos 8380
      pos 8396
      pos 8413
      pos 8464
      pos 8598
      pos 8722
      pos 8812
      pos 8911
      pos 9061
      pos 9155
      pos 9241
      pos 9623
      pos 9736
      pos 9809
      pos 9812
      pos 9872
      pos 10508
    doc 12
      freq 2
      pos 2192
      pos 7642
    doc 13
      freq 5
      pos 298
      pos 2417
      pos 3650
      pos 5042
      pos 5054
    doc 16
      freq 69
      pos 20
      pos 93
      pos 142
      pos 146
      pos 182
      pos 193
      pos 239
      pos 250
      pos 258
      pos 281
      pos 327
      pos 355
      pos 375
      pos 397
      pos 403
      pos 409
      pos 430
      pos 457
      pos 471
      pos 483
      pos 487
      pos 570
      pos 576
      pos 582
      pos 585
      pos 587
      pos 615
      pos 634
      pos 642
      pos 677
      pos 686
      pos 696
      pos 727
      pos 730
      pos 741
      pos 744
      pos 760
      pos 796
      pos 867
      pos 886
      pos 888
      pos 1019
      pos 1021
      pos 1068
      pos 1076
      pos 1088
      pos 1104
      pos 1106
      pos 1111
      pos 1135
      pos 1279
      pos 1332
      pos 1339
      pos 1381
      pos 1401
      pos 1406
      pos 1712
      pos 1728
      pos 1758
      pos 1882
      pos 1892
      pos 1975
      pos 2343
      pos 2468
      pos 2526
      pos 2549
      pos 2563
      pos 2585
      pos 2595
    doc 17
      freq 1
      pos 1187
    skipList 
      level 0
        skipDoc 12
        skipDocFP 1438325
        impacts 
          impact 
            freq 5
            norm 100
          impact 
            freq 13
            norm 104
          impact 
            freq 109
            norm 108
          impact 
            freq 110
            norm 114
        impactsEnd 
  term messages
    doc 1
      freq 11
      pos 298
      pos 2275
      pos 2720
      pos 4185
      pos 4267
      pos 4602
      pos 4812
      pos 4819
      pos 6301
      pos 8658
      pos 8682
    doc 4
      freq 59
      pos 112
      pos 184
      pos 210
      pos 232
      pos 331
      pos 344
      pos 374
      pos 384
      pos 514
      pos 580
      pos 684
      pos 691
      pos 694
      pos 696
      pos 717
      pos 726
      pos 759
      pos 762
      pos 801
      pos 804
      pos 830
      pos 962
      pos 1356
      pos 1836
      pos 1847
      pos 1870
      pos 1876
      pos 1926
      pos 2056
      pos 2068
      pos 2087
      pos 2700
      pos 2929
      pos 3541
      pos 3704
      pos 3712
      pos 3967
      pos 4018
      pos 4028
      pos 4100
      pos 4132
      pos 4180
      pos 4323
      pos 4353
      pos 4569
      pos 4608
      pos 4654
      pos 4692
      pos 4716
      pos 5141
      pos 5170
      pos 5600
      pos 5612
      pos 5647
      pos 5707
      pos 5717
      pos 5756
      pos 5850
      pos 5973
    doc 5
      freq 2
      pos 3452
      pos 3483
    doc 7
      freq 5
      pos 552
      pos 928
      pos 945
      pos 2004
      pos 2392
    doc 9
      freq 10
      pos 263
      pos 508
      pos 703
      pos 710
      pos 821
      pos 873
      pos 915
      pos 1035
      pos 1145
      pos 1460
    doc 10
      freq 13
      pos 132
      pos 369
      pos 3260
      pos 6030
      pos 6171
      pos 9294
      pos 9339
      pos 9347
      pos 11256
      pos 11434
      pos 12184
      pos 12207
      pos 13398
    doc 11
      freq 87
      pos 37
      pos 86
      pos 125
      pos 134
      pos 194
      pos 246
      pos 497
      pos 556
      pos 577
      pos 594
      pos 609
      pos 622
      pos 646
      pos 662
      pos 690
      pos 730
      pos 777
      pos 824
      pos 864
      pos 1050
      pos 1191
      pos 1198
      pos 1257
      pos 1443
      pos 1577
      pos 1901
      pos 2115
      pos 2295
      pos 2547
      pos 2788
      pos 3056
      pos 3323
      pos 3446
      pos 3691
      pos 3751
      pos 3756
      pos 3887
      pos 3988
      pos 4174
      pos 4179
      pos 4185
      pos 4203
      pos 4219
      pos 4414
      pos 4588
      pos 4657
      pos 4895
      pos 5073
      pos 5240
      pos 5306
      pos 5397
      pos 5545
      pos 5612
      pos 5705
      pos 5778
      pos 5837
      pos 6025
      pos 6249
      pos 6485
      pos 6721
      pos 6935
      pos 7145
      pos 7273
      pos 7365
      pos 7551
      pos 7785
      pos 7949
      pos 8032
      pos 8229
      pos 8461
      pos 8645
      pos 8864
      pos 8963
      pos 9208
      pos 9360
      pos 9418
      pos 9531
      pos 9541
      pos 9725
      pos 9756
      pos 9863
      pos 9870
      pos 10029
      pos 10219
      pos 10428
      pos 10521
      pos 10624
    doc 13
      freq 3
      pos 3987
      pos 4446
      pos 4454
    doc 15
      freq 3
      pos 1698
      pos 2613
      pos 3932
    doc 16
      freq 8
      pos 106
      pos 125
      pos 203
      pos 207
      pos 296
      pos 865
      pos 1355
      pos 2301
    doc 17
      freq 1
      pos 1175
    skipList 
      level 0
        skipDoc 13
        skipDocFP 1445632
        impacts 
          impact 
            freq 10
            norm 95
          impact 
            freq 59
            norm 108
          impact 
            freq 87
            norm 114
        impactsEnd 
  term messaging
    doc 13
      freq 1
      pos 3222
  term met
    doc 2
      freq 1
      pos 367
    doc 3
      freq 1
      pos 5660
    doc 9
      freq 1
      pos 397
    doc 14
      freq 2
      pos 654
      pos 1469
  term metadat
    doc 13
      freq 166
      pos 251
      pos 503
      pos 647
      pos 671
      pos 709
      pos 734
      pos 768
      pos 799
      pos 896
      pos 902
      pos 977
      pos 1044
      pos 1098
      pos 1234
      pos 1251
      pos 1268
      pos 1272
      pos 1281
      pos 1302
      pos 1327
      pos 1350
      pos 1369
      pos 1390
      pos 1394
      pos 1425
      pos 1444
      pos 1511
      pos 1668
      pos 1776
      pos 1786
      pos 1794
      pos 1847
      pos 1882
      pos 2095
      pos 2148
      pos 2188
      pos 2259
      pos 2303
      pos 2352
      pos 2375
      pos 2385
      pos 2407
      pos 2469
      pos 2498
      pos 2508
      pos 2700
      pos 2713
      pos 2838
      pos 2853
      pos 2856
      pos 2885
      pos 2915
      pos 3031
      pos 3175
      pos 3196
      pos 3338
      pos 3363
      pos 3414
      pos 3422
      pos 3454
      pos 3490
      pos 3547
      pos 3570
      pos 3631
      pos 3640
      pos 3645
      pos 3682
      pos 3734
      pos 3749
      pos 3779
      pos 4018
      pos 4036
      pos 4090
      pos 4225
      pos 4230
      pos 4339
      pos 4386
      pos 4398
      pos 4432
      pos 4460
      pos 4475
      pos 4519
      pos 4542
      pos 4550
      pos 4569
      pos 4574
      pos 4582
      pos 4587
      pos 4711
      pos 4726
      pos 4741
      pos 4752
      pos 4779
      pos 4805
      pos 4817
      pos 4857
      pos 4892
      pos 4900
      pos 4965
      pos 4973
      pos 4984
      pos 5007
      pos 5134
      pos 5150
      pos 5168
      pos 5185
      pos 5202
      pos 5223
      pos 5272
      pos 5301
      pos 5314
      pos 5331
      pos 5343
      pos 5349
      pos 5393
      pos 5419
      pos 5433
      pos 5469
      pos 5487
      pos 5506
      pos 5521
      pos 5532
      pos 5536
      pos 5547
      pos 5553
      pos 5576
      pos 5595
      pos 5612
      pos 5621
      pos 5682
      pos 5697
      pos 5715
      pos 5744
      pos 5790
      pos 5828
      pos 5845
      pos 5868
      pos 5885
      pos 5911
      pos 5939
      pos 5952
      pos 5962
      pos 6022
      pos 6025
      pos 6076
      pos 6088
      pos 6092
      pos 6097
      pos 6142
      pos 6152
      pos 6168
      pos 6177
      pos 6211
      pos 6228
      pos 6251
      pos 6263
      pos 6284
      pos 6370
      pos 6459
      pos 6493
      pos 6520
      pos 6550
      pos 6586
      pos 6615
      pos 6703
      pos 6723
  term method
    doc 1
      freq 11
      pos 1775
      pos 1798
      pos 2382
      pos 3742
      pos 4872
      pos 4927
      pos 4934
      pos 4963
      pos 4970
      pos 5810
      pos 7880
    doc 2
      freq 8
      pos 2609
      pos 3295
      pos 5807
      pos 5842
      pos 5850
      pos 5869
      pos 5922
      pos 5946
    doc 3
      freq 3
      pos 1458
      pos 4440
      pos 4484
    doc 4
      freq 2
      pos 1886
      pos 5605
    doc 5
      freq 1
      pos 811
    doc 7
      freq 1
      pos 2810
    doc 9
      freq 3
      pos 1200
      pos 1219
      pos 1285
    doc 10
      freq 13
      pos 4980
      pos 4981
      pos 5014
      pos 5334
      pos 5857
      pos 5860
      pos 5887
      pos 8659
      pos 11307
      pos 11614
      pos 11709
      pos 11810
      pos 11904
    doc 11
      freq 15
      pos 369
      pos 374
      pos 377
      pos 1610
      pos 1628
      pos 1635
      pos 1643
      pos 2447
      pos 6729
      pos 6738
      pos 6797
      pos 6800
      pos 6807
      pos 6815
      pos 8016
    doc 12
      freq 1
      pos 7559
    doc 13
      freq 2
      pos 4026
      pos 6701
    doc 14
      freq 39
      pos 133
      pos 151
      pos 206
      pos 237
      pos 246
      pos 254
      pos 262
      pos 435
      pos 467
      pos 483
      pos 595
      pos 603
      pos 610
      pos 617
      pos 685
      pos 1120
      pos 1122
      pos 1160
      pos 1176
      pos 1182
      pos 1365
      pos 2442
      pos 2505
      pos 2514
      pos 2696
      pos 2705
      pos 2709
      pos 2736
      pos 2767
      pos 2832
      pos 2840
      pos 2872
      pos 2883
      pos 2959
      pos 4151
      pos 4879
      pos 5133
      pos 5315
      pos 5325
    doc 15
      freq 1
      pos 927
    skipList 
      level 0
        skipDoc 10
        skipDocFP 1451926
        impacts 
          impact 
            freq 3
            norm 95
          impact 
            freq 8
            norm 108
          impact 
            freq 11
            norm 113
          impact 
            freq 13
            norm 116
        impactsEnd 
  term method0123456789_
    doc 11
      freq 2
      pos 1909
      pos 1988
  term methodology
    doc 3
      freq 1
      pos 4238
  term methods
    doc 1
      freq 8
      pos 563
      pos 652
      pos 721
      pos 7604
      pos 9036
      pos 9060
      pos 9082
      pos 9109
    doc 2
      freq 8
      pos 1400
      pos 2376
      pos 4961
      pos 5715
      pos 5744
      pos 5765
      pos 5908
      pos 5934
    doc 3
      freq 3
      pos 31
      pos 3953
      pos 4123
    doc 4
      freq 1
      pos 5590
    doc 5
      freq 3
      pos 468
      pos 803
      pos 1016
    doc 6
      freq 4
      pos 313
      pos 470
      pos 490
      pos 506
    doc 8
      freq 4
      pos 1911
      pos 1949
      pos 1971
      pos 1996
    doc 9
      freq 1
      pos 1410
    doc 11
      freq 1
      pos 1882
    doc 12
      freq 4
      pos 1888
      pos 2341
      pos 4553
      pos 5275
    doc 13
      freq 3
      pos 1060
      pos 2598
      pos 6310
    doc 14
      freq 4
      pos 73
      pos 87
      pos 411
      pos 431
    doc 15
      freq 2
      pos 2239
      pos 3132
    skipList 
      level 0
        skipDoc 9
        skipDocFP 1454214
        impacts 
          impact 
            freq 1
            norm 95
          impact 
            freq 4
            norm 97
          impact 
            freq 8
            norm 108
        impactsEnd 
  term metric
    doc 0
      freq 20
      pos 1714
      pos 1725
      pos 1729
      pos 1755
      pos 1765
      pos 1806
      pos 1838
      pos 2483
      pos 3584
      pos 3934
      pos 3965
      pos 5152
      pos 5181
      pos 6411
      pos 6453
      pos 10478
      pos 10517
      pos 11508
      pos 11543
      pos 11572
    doc 6
      freq 3
      pos 803
      pos 831
      pos 3018
  term metrics
    doc 0
      freq 7
      pos 1772
      pos 1816
      pos 1864
      pos 1867
      pos 16039
      pos 16358
      pos 16419
    doc 6
      freq 1
      pos 3022
    doc 12
      freq 1
      pos 2736
  term metropolitan
    doc 2
      freq 8
      pos 2486
      pos 2507
      pos 2536
      pos 2562
      pos 2592
      pos 2633
      pos 2712
      pos 3430
    doc 3
      freq 2
      pos 4423
      pos 4457
  term metz
    doc 8
      freq 1
      pos 2015
  term meyer
    doc 2
      freq 1
      pos 6363
  term mf
    doc 11
      freq 1
      pos 10071
  term mfs5p8g6y
    doc 11
      freq 1
      pos 10345
  term mfuy4z
    doc 11
      freq 1
      pos 10406
  term mfwwfv1zn4pvl4eqljr
    doc 11
      freq 1
      pos 10433
  term mg77
    doc 11
      freq 1
      pos 10281
  term mgmt
    doc 5
      freq 1
      pos 2701
  term mhandley
    doc 11
      freq 20
      pos 1535
      pos 2253
      pos 3171
      pos 3404
      pos 4047
      pos 4312
      pos 4493
      pos 4707
      pos 5198
      pos 5355
      pos 5503
      pos 5663
      pos 5983
      pos 6207
      pos 6897
      pos 7231
      pos 8187
      pos 8516
      pos 9111
      pos 9288
  term mhqtevpd
    doc 10
      freq 1
      pos 12806
  term mib
    doc 0
      freq 154
      pos 99
      pos 115
      pos 159
      pos 189
      pos 237
      pos 238
      pos 253
      pos 271
      pos 386
      pos 401
      pos 404
      pos 407
      pos 412
      pos 420
      pos 427
      pos 454
      pos 490
      pos 664
      pos 825
      pos 997
      pos 1005
      pos 1007
      pos 1028
      pos 1048
      pos 1054
      pos 1059
      pos 1067
      pos 1206
      pos 1219
      pos 1247
      pos 1255
      pos 1404
      pos 1616
      pos 1782
      pos 1923
      pos 2099
      pos 2331
      pos 2541
      pos 2722
      pos 2901
      pos 3089
      pos 3250
      pos 3461
      pos 3673
      pos 3808
      pos 4019
      pos 4204
      pos 4407
      pos 4550
      pos 4707
      pos 4823
      pos 5045
      pos 5239
      pos 5476
      pos 5590
      pos 5772
      pos 5953
      pos 6181
      pos 6346
      pos 6436
      pos 6656
      pos 6910
      pos 7089
      pos 7253
      pos 7354
      pos 7516
      pos 7681
      pos 7820
      pos 7954
      pos 8138
      pos 8333
      pos 8423
      pos 8642
      pos 8830
      pos 8930
      pos 9082
      pos 9247
      pos 9441
      pos 9597
      pos 9741
      pos 9907
      pos 10047
      pos 10173
      pos 10387
      pos 10586
      pos 10607
      pos 10812
      pos 11024
      pos 11098
      pos 11306
      pos 11487
      pos 11645
      pos 11776
      pos 11882
      pos 12053
      pos 12180
      pos 12316
      pos 12469
      pos 12641
      pos 12789
      pos 12994
      pos 13185
      pos 13344
      pos 13544
      pos 13738
      pos 13928
      pos 14139
      pos 14326
      pos 14400
      pos 14456
      pos 14480
      pos 14503
      pos 14516
      pos 14566
      pos 14622
      pos 14646
      pos 14669
      pos 14682
      pos 14706
      pos 14730
      pos 14768
      pos 14807
      pos 14813
      pos 14927
      pos 15054
      pos 15181
      pos 15311
      pos 15400
      pos 15422
      pos 15493
      pos 15564
      pos 15642
      pos 15726
      pos 15803
      pos 15810
      pos 15834
      pos 15840
      pos 15869
      pos 15984
      pos 15996
      pos 16101
      pos 16135
      pos 16324
      pos 16476
      pos 16609
      pos 16665
      pos 16696
      pos 16701
      pos 16797
      pos 16847
      pos 16853
      pos 16989
      pos 17105
      pos 17220
    doc 2
      freq 57
      pos 135
      pos 172
      pos 242
      pos 251
      pos 256
      pos 262
      pos 266
      pos 272
      pos 277
      pos 1171
      pos 1209
      pos 1245
      pos 1260
      pos 1271
      pos 1277
      pos 1330
      pos 1354
      pos 1365
      pos 1682
      pos 2463
      pos 2473
      pos 2826
      pos 2831
      pos 3193
      pos 3361
      pos 3500
      pos 3505
      pos 3547
      pos 3557
      pos 3580
      pos 3651
      pos 3699
      pos 3795
      pos 3825
      pos 3929
      pos 3952
      pos 3975
      pos 4001
      pos 4007
      pos 4108
      pos 4131
      pos 4236
      pos 4286
      pos 4310
      pos 4332
      pos 4340
      pos 4363
      pos 4393
      pos 4440
      pos 4529
      pos 4537
      pos 4587
      pos 4609
      pos 4624
      pos 4694
      pos 4742
      pos 4777
    doc 3
      freq 5
      pos 3233
      pos 3256
      pos 3259
      pos 4533
      pos 4590
    doc 6
      freq 1
      pos 134
    doc 7
      freq 12
      pos 777
      pos 855
      pos 982
      pos 1043
      pos 1074
      pos 2132
      pos 2141
      pos 2171
      pos 2265
      pos 2434
      pos 2588
      pos 2648
  term mibs
    doc 2
      freq 21
      pos 78
      pos 225
      pos 1223
      pos 1238
      pos 1292
      pos 1340
      pos 1747
      pos 3520
      pos 3670
      pos 3757
      pos 3923
      pos 4076
      pos 4173
      pos 4370
      pos 4411
      pos 4447
      pos 4466
      pos 4487
      pos 4497
      pos 4514
      pos 4676
    doc 7
      freq 4
      pos 699
      pos 702
      pos 1995
      pos 1998
  term mice.cs.ucl.ac.uk
    doc 13
      freq 1
      pos 6799
  term michael
    doc 12
      freq 1
      pos 6771
  term mick
    doc 2
      freq 2
      pos 3600
      pos 3627
  term microsoft
    doc 2
      freq 2
      pos 6378
      pos 6380
  term microsoft.com
    doc 2
      freq 1
      pos 6388
  term mid
    doc 4
      freq 1
      pos 2022
    doc 10
      freq 2
      pos 4542
      pos 4604
  term middl
    doc 5
      freq 4
      pos 306
      pos 2976
      pos 3004
      pos 3468
    doc 10
      freq 8
      pos 9178
      pos 9289
      pos 9330
      pos 9438
      pos 9457
      pos 9852
      pos 9882
      pos 10185
    doc 12
      freq 1
      pos 9192
  term middlbury
    doc 0
      freq 1
      pos 1118
  term middlebury
    doc 0
      freq 4
      pos 1111
      pos 1113
      pos 17203
      pos 17205
  term middlebury.edu
    doc 0
      freq 1
      pos 17210
  term midnight
    doc 0
      freq 2
      pos 1078
      pos 1239
  term might
    doc 0
      freq 4
      pos 9197
      pos 17353
      pos 17380
      pos 17382
    doc 1
      freq 7
      pos 4474
      pos 4491
      pos 6990
      pos 8466
      pos 9734
      pos 9761
      pos 9763
    doc 2
      freq 5
      pos 2103
      pos 6115
      pos 6531
      pos 6558
      pos 6560
    doc 3
      freq 6
      pos 1736
      pos 2392
      pos 2782
      pos 6083
      pos 6110
      pos 6112
    doc 4
      freq 5
      pos 4677
      pos 4679
      pos 6238
      pos 6265
      pos 6267
    doc 5
      freq 10
      pos 2907
      pos 3289
      pos 3315
      pos 3429
      pos 3470
      pos 3564
      pos 3605
      pos 4568
      pos 4595
      pos 4597
    doc 6
      freq 4
      pos 2669
      pos 3368
      pos 3395
      pos 3397
    doc 7
      freq 4
      pos 1551
      pos 3073
      pos 3100
      pos 3102
    doc 8
      freq 3
      pos 2290
      pos 2317
      pos 2319
    doc 9
      freq 4
      pos 1404
      pos 1935
      pos 1962
      pos 1964
    doc 10
      freq 24
      pos 815
      pos 1178
      pos 2214
      pos 2568
      pos 2758
      pos 2804
      pos 2826
      pos 2841
      pos 2865
      pos 2915
      pos 2950
      pos 8820
      pos 9439
      pos 9570
      pos 9605
      pos 9662
      pos 9674
      pos 9883
      pos 10415
      pos 10940
      pos 11389
      pos 13596
      pos 13623
      pos 13625
    doc 11
      freq 5
      pos 2043
      pos 7483
      pos 10757
      pos 10784
      pos 10786
    doc 12
      freq 17
      pos 3333
      pos 3396
      pos 3561
      pos 4588
      pos 5777
      pos 5912
      pos 5914
      pos 6336
      pos 6470
      pos 6485
      pos 8713
      pos 9133
      pos 9207
      pos 9215
      pos 9607
      pos 9634
      pos 9636
    doc 13
      freq 7
      pos 3728
      pos 4418
      pos 4450
      pos 4588
      pos 7222
      pos 7249
      pos 7251
    doc 14
      freq 5
      pos 370
      pos 2146
      pos 5688
      pos 5715
      pos 5717
    doc 15
      freq 6
      pos 472
      pos 487
      pos 1868
      pos 4207
      pos 4234
      pos 4236
    doc 16
      freq 4
      pos 1342
      pos 2818
      pos 2845
      pos 2847
    doc 17
      freq 4
      pos 1132
      pos 2542
      pos 2569
      pos 2571
    doc 18
      freq 5
      pos 983
      pos 1125
      pos 2330
      pos 2357
      pos 2359
    skipList 
      level 0
        skipDoc 7
        skipDocFP 1462176
        impacts 
          impact 
            freq 4
            norm 100
          impact 
            freq 10
            norm 104
        impactsEnd 
        skipDoc 15
        skipDocFP 1463039
        impacts 
          impact 
            freq 4
            norm 95
          impact 
            freq 6
            norm 104
          impact 
            freq 7
            norm 109
          impact 
            freq 17
            norm 113
          impact 
            freq 24
            norm 116
        impactsEnd 
  term migration
    doc 12
      freq 1
      pos 2035
  term miic1jccaj
    doc 10
      freq 1
      pos 6879
  term miic3tccakagawibagibadanbgkqhkig9w0baqufadbzmqswcqydvqqgewjvuzel
    doc 10
      freq 1
      pos 6248
  term miicxgibaakbgqc
    doc 10
      freq 1
      pos 6832
  term miicxqibaakbgqdppmbthvopkxv
    doc 10
      freq 1
      pos 6208
  term mike
    doc 0
      freq 1
      pos 15911
  term mikey
    doc 5
      freq 60
      pos 202
      pos 224
      pos 234
      pos 272
      pos 595
      pos 598
      pos 658
      pos 724
      pos 735
      pos 765
      pos 800
      pos 881
      pos 1019
      pos 1043
      pos 1150
      pos 1170
      pos 1190
      pos 1485
      pos 1502
      pos 1524
      pos 1658
      pos 1703
      pos 2131
      pos 2144
      pos 2225
      pos 2266
      pos 2281
      pos 2291
      pos 2324
      pos 2333
      pos 2365
      pos 2388
      pos 2391
      pos 2397
      pos 2400
      pos 2417
      pos 2468
      pos 2494
      pos 2521
      pos 2527
      pos 2579
      pos 2598
      pos 2669
      pos 2819
      pos 2826
      pos 2857
      pos 2890
      pos 2891
      pos 3066
      pos 3123
      pos 3275
      pos 3399
      pos 3420
      pos 3638
      pos 3710
      pos 3748
      pos 4174
      pos 4249
      pos 4387
      pos 4388
  term mikey's
    doc 5
      freq 2
      pos 293
      pos 2564
  term mile
    doc 13
      freq 1
      pos 2533
  term military
    doc 5
      freq 1
      pos 3602
  term milliseconds
    doc 0
      freq 6
      pos 6841
      pos 6852
      pos 6935
      pos 6945
      pos 6982
      pos 6995
    doc 4
      freq 1
      pos 1970
    doc 5
      freq 1
      pos 1395
    doc 6
      freq 2
      pos 1341
      pos 1369
  term mills
    doc 5
      freq 1
      pos 4288
  term mime
    doc 7
      freq 6
      pos 938
      pos 1111
      pos 2617
      pos 2690
      pos 2762
      pos 2770
    doc 10
      freq 8
      pos 240
      pos 250
      pos 536
      pos 562
      pos 6187
      pos 6813
      pos 8307
      pos 12399
    doc 11
      freq 8
      pos 231
      pos 3538
      pos 3696
      pos 3750
      pos 3755
      pos 9509
      pos 9519
      pos 9804
    doc 16
      freq 12
      pos 1086
      pos 1118
      pos 1131
      pos 1149
      pos 1156
      pos 1727
      pos 1807
      pos 2003
      pos 2068
      pos 2188
      pos 2371
      pos 2579
  term mimuhlbhbq0cydwasbqkirc3jqzfqhspp
    doc 11
      freq 1
      pos 10054
  term min
    doc 0
      freq 44
      pos 14824
      pos 14836
      pos 14848
      pos 14860
      pos 14872
      pos 14884
      pos 14896
      pos 14908
      pos 14932
      pos 14944
      pos 14956
      pos 14968
      pos 14980
      pos 14992
      pos 15004
      pos 15016
      pos 15028
      pos 15040
      pos 15064
      pos 15076
      pos 15088
      pos 15100
      pos 15112
      pos 15124
      pos 15136
      pos 15148
      pos 15160
      pos 15184
      pos 15196
      pos 15208
      pos 15220
      pos 15232
      pos 15244
      pos 15256
      pos 15268
      pos 15280
      pos 15292
      pos 15316
      pos 15328
      pos 15340
      pos 15352
      pos 15364
      pos 15376
      pos 15388
    doc 6
      freq 7
      pos 1522
      pos 1565
      pos 1894
      pos 1901
      pos 1922
      pos 2363
      pos 2718
  term minat
    doc 3
      freq 2
      pos 880
      pos 897
  term mind
    doc 12
      freq 1
      pos 1164
    doc 15
      freq 1
      pos 329
  term minimal
    doc 0
      freq 2
      pos 6990
      pos 16503
    doc 6
      freq 2
      pos 2523
      pos 2564
  term minimally
    doc 14
      freq 1
      pos 5474
    doc 18
      freq 4
      pos 23
      pos 162
      pos 570
      pos 1788
  term minimis
    doc 14
      freq 1
      pos 2425
  term minimising
    doc 14
      freq 1
      pos 2129
  term minimiz
    doc 18
      freq 1
      pos 1179
  term minimizing
    doc 12
      freq 1
      pos 2354
  term minimum
    doc 0
      freq 3
      pos 4833
      pos 7030
      pos 7165
    doc 4
      freq 6
      pos 1464
      pos 1588
      pos 2145
      pos 2811
      pos 3056
      pos 3292
    doc 6
      freq 3
      pos 1288
      pos 1303
      pos 1580
    doc 12
      freq 3
      pos 3212
      pos 4820
      pos 5217
    doc 14
      freq 13
      pos 760
      pos 793
      pos 937
      pos 984
      pos 1451
      pos 1498
      pos 1636
      pos 2029
      pos 2189
      pos 3245
      pos 3281
      pos 5002
      pos 5019
  term minimumbroadcastlsptransmissioninterval
    doc 0
      freq 1
      pos 7008
  term minimumlspgenerationinterval
    doc 0
      freq 1
      pos 4855
  term minimumlsptransmissioninterval
    doc 0
      freq 1
      pos 7074
  term minimums
    doc 6
      freq 2
      pos 1069
      pos 1114
  term minor
    doc 2
      freq 1
      pos 4681
    doc 4
      freq 1
      pos 5763
  term minus
    doc 3
      freq 1
      pos 1609
  term minut
    doc 9
      freq 1
      pos 1380
  term minutes
    doc 10
      freq 2
      pos 3174
      pos 3198
  term mirror
    doc 6
      freq 1
      pos 2606
  term mis
    doc 1
      freq 2
      pos 2364
      pos 7854
  term misbehav
    doc 9
      freq 1
      pos 331
  term misbehaving
    doc 12
      freq 1
      pos 1843
    doc 16
      freq 1
      pos 1372
  term misbehavior
    doc 12
      freq 14
      pos 90
      pos 214
      pos 217
      pos 226
      pos 1619
      pos 1623
      pos 1653
      pos 1666
      pos 1678
      pos 1903
      pos 1910
      pos 3493
      pos 7375
      pos 7752
  term misbehaviors
    doc 12
      freq 1
      pos 652
  term miscellaneous
    doc 12
      freq 5
      pos 121
      pos 409
      pos 714
      pos 6492
      pos 6498
  term misconfiguration
    doc 1
      freq 2
      pos 2375
      pos 7871
  term misconfigured
    doc 6
      freq 1
      pos 2312
  term misdirected
    doc 13
      freq 1
      pos 5760
  term misguided
    doc 18
      freq 1
      pos 1906
  term mishr
    doc 2
      freq 4
      pos 2846
      pos 2847
      pos 4895
      pos 5127
  term misleading
    doc 13
      freq 1
      pos 5036
  term mismatch
    doc 0
      freq 1
      pos 8047
    doc 11
      freq 4
      pos 370
      pos 378
      pos 6730
      pos 6801
  term mismatch01
    doc 11
      freq 2
      pos 6762
      pos 6781
  term mismatch02
    doc 11
      freq 2
      pos 6854
      pos 6873
  term mismatches
    doc 0
      freq 3
      pos 7387
      pos 7400
      pos 7616
  term mismatching
    doc 11
      freq 1
      pos 6734
  term misordered
    doc 3
      freq 1
      pos 2988
  term misordering
    doc 3
      freq 2
      pos 3325
      pos 3355
  term miss
    doc 15
      freq 1
      pos 2533
  term missed
    doc 13
      freq 1
      pos 2297
  term missing
    doc 11
      freq 6
      pos 391
      pos 401
      pos 6548
      pos 7019
      pos 7166
      pos 7192
    doc 12
      freq 1
      pos 9307
  term mistaken
    doc 3
      freq 1
      pos 3409
  term mistry
    doc 11
      freq 1
      pos 9591
  term mitigat
    doc 12
      freq 1
      pos 1860
    doc 13
      freq 1
      pos 6639
  term mitigates
    doc 4
      freq 1
      pos 4649
    doc 10
      freq 1
      pos 5299
  term mitigating
    doc 13
      freq 1
      pos 6685
  term mitton
    doc 2
      freq 2
      pos 3053
      pos 3110
  term mix
    doc 11
      freq 1
      pos 1262
    doc 15
      freq 2
      pos 1654
      pos 2483
  term mixed
    doc 11
      freq 2
      pos 3540
      pos 3836
    doc 15
      freq 1
      pos 514
    doc 16
      freq 2
      pos 1726
      pos 2020
  term mjr5hou03rvebbps
    doc 11
      freq 1
      pos 10253
  term mjx
    doc 11
      freq 1
      pos 10393
  term mkqgfkr
    doc 10
      freq 1
      pos 12470
  term mlr
    doc 6
      freq 5
      pos 1160
      pos 2179
      pos 2450
      pos 2649
      pos 2715
  term mm
    doc 11
      freq 1
      pos 10471
  term mmusic
    doc 13
      freq 2
      pos 1173
      pos 1563
  term mn58lvzptzg
    doc 11
      freq 1
      pos 10123
  term mo
    doc 11
      freq 1
      pos 10559
  term mobil
    doc 2
      freq 2
      pos 2722
      pos 2739
    doc 9
      freq 25
      pos 18
      pos 89
      pos 170
      pos 191
      pos 221
      pos 254
      pos 324
      pos 398
      pos 421
      pos 434
      pos 566
      pos 667
      pos 677
      pos 765
      pos 791
      pos 801
      pos 1016
      pos 1147
      pos 1172
      pos 1324
      pos 1359
      pos 1464
      pos 1480
      pos 1607
      pos 1749
    doc 13
      freq 2
      pos 947
      pos 2074
  term mobility
    doc 9
      freq 3
      pos 545
      pos 1391
      pos 1657
  term mockapetris
    doc 12
      freq 1
      pos 6998
    doc 14
      freq 2
      pos 5363
      pos 5377
  term mod
    doc 17
      freq 4
      pos 2186
      pos 2189
      pos 2226
      pos 2251
  term mode
    doc 0
      freq 2
      pos 14780
      pos 16908
    doc 1
      freq 5
      pos 115
      pos 1849
      pos 1854
      pos 1987
      pos 2063
    doc 3
      freq 29
      pos 202
      pos 207
      pos 224
      pos 227
      pos 1129
      pos 1132
      pos 1135
      pos 1186
      pos 1697
      pos 1715
      pos 1819
      pos 1840
      pos 1845
      pos 1863
      pos 1898
      pos 2326
      pos 2329
      pos 2490
      pos 2545
      pos 2602
      pos 2608
      pos 2699
      pos 2734
      pos 2798
      pos 2807
      pos 5162
      pos 5207
      pos 5255
      pos 5267
    doc 5
      freq 1
      pos 4382
    doc 8
      freq 8
      pos 635
      pos 653
      pos 703
      pos 712
      pos 725
      pos 768
      pos 773
      pos 784
    doc 13
      freq 1
      pos 6477
    doc 15
      freq 1
      pos 427
  term model
    doc 1
      freq 5
      pos 1056
      pos 1111
      pos 2186
      pos 3346
      pos 3586
    doc 2
      freq 4
      pos 3809
      pos 3835
      pos 3921
      pos 4194
    doc 3
      freq 4
      pos 751
      pos 858
      pos 3221
      pos 3227
    doc 11
      freq 1
      pos 9664
    doc 12
      freq 1
      pos 8759
    doc 13
      freq 5
      pos 4784
      pos 4809
      pos 5355
      pos 5369
      pos 5582
  term models
    doc 1
      freq 5
      pos 1001
      pos 1953
      pos 1965
      pos 3328
      pos 4471
    doc 3
      freq 1
      pos 559
    doc 12
      freq 1
      pos 6867
    doc 13
      freq 1
      pos 1886
  term modem
    doc 7
      freq 2
      pos 1039
      pos 2584
  term modes
    doc 3
      freq 4
      pos 1127
      pos 2611
      pos 2677
      pos 5435
    doc 7
      freq 2
      pos 834
      pos 2244
    doc 13
      freq 2
      pos 3138
      pos 3207
  term modest
    doc 6
      freq 1
      pos 2553
  term modification
    doc 5
      freq 1
      pos 3231
    doc 12
      freq 1
      pos 6109
    doc 14
      freq 2
      pos 1326
      pos 2453
  term modifications
    doc 2
      freq 1
      pos 3056
    doc 14
      freq 2
      pos 191
      pos 2346
    doc 18
      freq 1
      pos 2116
  term modified
    doc 0
      freq 14
      pos 1172
      pos 2233
      pos 2354
      pos 2497
      pos 3303
      pos 3910
      pos 4422
      pos 4784
      pos 5616
      pos 5706
      pos 5860
      pos 10141
      pos 11440
      pos 15866
    doc 1
      freq 2
      pos 1715
      pos 1732
    doc 3
      freq 1
      pos 1726
    doc 10
      freq 1
      pos 6805
    doc 12
      freq 2
      pos 4839
      pos 5238
    doc 13
      freq 2
      pos 986
      pos 6357
    doc 14
      freq 19
      pos 150
      pos 205
      pos 253
      pos 261
      pos 466
      pos 609
      pos 616
      pos 1119
      pos 1349
      pos 2441
      pos 2504
      pos 2513
      pos 2704
      pos 2766
      pos 2839
      pos 2871
      pos 4878
      pos 5132
      pos 5314
  term modifier
    doc 12
      freq 1
      pos 5895
  term modifies
    doc 5
      freq 1
      pos 3180
  term modify
    doc 0
      freq 2
      pos 3558
      pos 16624
    doc 5
      freq 4
      pos 3209
      pos 3292
      pos 3318
      pos 3388
    doc 10
      freq 6
      pos 4751
      pos 9180
      pos 9241
      pos 9271
      pos 9442
      pos 10153
    doc 13
      freq 1
      pos 1387
    doc 14
      freq 1
      pos 393
    doc 15
      freq 1
      pos 2297
  term modifying
    doc 12
      freq 1
      pos 2425
  term modul
    doc 0
      freq 17
      pos 272
      pos 1020
      pos 1034
      pos 1070
      pos 1220
      pos 14385
      pos 14530
      pos 14532
      pos 14550
      pos 14744
      pos 14746
      pos 14761
      pos 14814
      pos 14816
      pos 15811
      pos 16798
      pos 16854
    doc 2
      freq 1
      pos 4610
    doc 3
      freq 1
      pos 3257
    doc 17
      freq 2
      pos 1652
      pos 2168
  term modularity
    doc 13
      freq 2
      pos 259
      pos 3819
  term modules
    doc 17
      freq 1
      pos 1479
  term mogul
    doc 4
      freq 1
      pos 5353
    doc 13
      freq 1
      pos 6885
  term mogxsvcx05ukq
    doc 10
      freq 1
      pos 12612
  term monitor
    doc 6
      freq 1
      pos 460
  term monitored
    doc 0
      freq 1
      pos 14794
  term monitoring
    doc 6
      freq 7
      pos 198
      pos 563
      pos 846
      pos 976
      pos 1107
      pos 1380
      pos 2711
    doc 7
      freq 2
      pos 981
      pos 2433
  term montenegr
    doc 9
      freq 1
      pos 1744
  term month
    doc 9
      freq 1
      pos 1388
    doc 10
      freq 3
      pos 5068
      pos 5088
      pos 5127
    doc 12
      freq 1
      pos 5774
  term months
    doc 2
      freq 1
      pos 738
    doc 7
      freq 1
      pos 595
    doc 12
      freq 1
      pos 6653
    doc 13
      freq 1
      pos 3600
  term moo6tp3ub75uf6tlipxpddh5dwvbp7vczv
    doc 10
      freq 1
      pos 12561
  term moore
    doc 12
      freq 1
      pos 7146
  term moot
    doc 10
      freq 1
      pos 7689
  term more
    doc 0
      freq 6
      pos 1930
      pos 3106
      pos 3647
      pos 4163
      pos 11005
      pos 13385
    doc 1
      freq 7
      pos 2101
      pos 3142
      pos 4053
      pos 4591
      pos 4738
      pos 5047
      pos 5154
    doc 2
      freq 7
      pos 410
      pos 434
      pos 735
      pos 813
      pos 3889
      pos 4191
      pos 4952
    doc 3
      freq 5
      pos 708
      pos 2638
      pos 3949
      pos 4229
      pos 5423
    doc 4
      freq 7
      pos 545
      pos 1091
      pos 1239
      pos 2679
      pos 3449
      pos 3655
      pos 5560
    doc 5
      freq 3
      pos 1639
      pos 3620
      pos 3766
    doc 6
      freq 4
      pos 173
      pos 607
      pos 1629
      pos 2075
    doc 7
      freq 1
      pos 1673
    doc 9
      freq 2
      pos 569
      pos 1305
    doc 10
      freq 17
      pos 1594
      pos 2155
      pos 2178
      pos 2464
      pos 2497
      pos 2861
      pos 3135
      pos 3195
      pos 3282
      pos 3408
      pos 4032
      pos 4401
      pos 5286
      pos 5442
      pos 5475
      pos 6151
      pos 7537
    doc 11
      freq 2
      pos 4425
      pos 5004
    doc 12
      freq 27
      pos 533
      pos 625
      pos 788
      pos 1140
      pos 1894
      pos 2030
      pos 2084
      pos 2470
      pos 2883
      pos 3200
      pos 3827
      pos 3946
      pos 4254
      pos 4305
      pos 4402
      pos 5046
      pos 5200
      pos 5253
      pos 5450
      pos 6000
      pos 6047
      pos 6360
      pos 6489
      pos 6722
      pos 8843
      pos 8963
      pos 9080
    doc 13
      freq 23
      pos 398
      pos 497
      pos 504
      pos 1277
      pos 1354
      pos 1481
      pos 1560
      pos 2184
      pos 2358
      pos 2547
      pos 2645
      pos 2779
      pos 3747
      pos 3796
      pos 3925
      pos 4990
      pos 5155
      pos 5268
      pos 5413
      pos 5667
      pos 5673
      pos 5678
      pos 6712
    doc 14
      freq 15
      pos 476
      pos 498
      pos 502
      pos 917
      pos 971
      pos 1169
      pos 1263
      pos 1304
      pos 1396
      pos 1573
      pos 1623
      pos 4976
      pos 5149
      pos 5287
      pos 5308
    doc 15
      freq 2
      pos 3130
      pos 3589
    doc 16
      freq 1
      pos 575
    doc 17
      freq 4
      pos 146
      pos 952
      pos 1345
      pos 1937
    doc 18
      freq 3
      pos 547
      pos 1680
      pos 1891
    skipList 
      level 0
        skipDoc 7
        skipDocFP 1479284
        impacts 
          impact 
            freq 1
            norm 100
          impact 
            freq 4
            norm 101
          impact 
            freq 5
            norm 107
          impact 
            freq 7
            norm 108
        impactsEnd 
        skipDoc 16
        skipDocFP 1480062
        impacts 
          impact 
            freq 2
            norm 95
          impact 
            freq 15
            norm 107
          impact 
            freq 23
            norm 109
          impact 
            freq 27
            norm 113
        impactsEnd 
  term morehous
    doc 16
      freq 1
      pos 2656
  term moreover
    doc 3
      freq 1
      pos 2948
    doc 5
      freq 3
      pos 1162
      pos 2475
      pos 3238
    doc 10
      freq 5
      pos 1680
      pos 8693
      pos 9466
      pos 10263
      pos 10878
    doc 12
      freq 1
      pos 5662
    doc 14
      freq 1
      pos 2468
  term morfin
    doc 12
      freq 1
      pos 6801
  term morishit
    doc 12
      freq 1
      pos 7369
  term morse
    doc 18
      freq 1
      pos 2165
  term most
    doc 0
      freq 1
      pos 9332
    doc 2
      freq 5
      pos 1430
      pos 2210
      pos 4436
      pos 5958
      pos 6210
    doc 3
      freq 2
      pos 2643
      pos 5142
    doc 7
      freq 1
      pos 1784
    doc 8
      freq 1
      pos 195
    doc 9
      freq 1
      pos 904
    doc 10
      freq 4
      pos 5721
      pos 7663
      pos 9081
      pos 10164
    doc 11
      freq 2
      pos 2414
      pos 5911
    doc 12
      freq 5
      pos 1634
      pos 2108
      pos 2389
      pos 2472
      pos 6578
    doc 13
      freq 1
      pos 2285
    doc 14
      freq 32
      pos 523
      pos 548
      pos 749
      pos 780
      pos 787
      pos 815
      pos 822
      pos 855
      pos 966
      pos 1007
      pos 1014
      pos 1070
      pos 1412
      pos 1440
      pos 1485
      pos 1492
      pos 1515
      pos 1589
      pos 1616
      pos 1659
      pos 1666
      pos 1722
      pos 3233
      pos 3271
      pos 3277
      pos 4310
      pos 4433
      pos 4440
      pos 4992
      pos 4998
      pos 5015
      pos 5167
    doc 15
      freq 3
      pos 140
      pos 792
      pos 909
    doc 17
      freq 1
      pos 491
    skipList 
      level 0
        skipDoc 11
        skipDocFP 1482914
        impacts 
          impact 
            freq 1
            norm 95
          impact 
            freq 2
            norm 107
          impact 
            freq 5
            norm 108
        impactsEnd 
  term mostly
    doc 0
      freq 1
      pos 16642
    doc 2
      freq 2
      pos 3836
      pos 3895
    doc 13
      freq 1
      pos 1954
  term motivated
    doc 10
      freq 1
      pos 8145
  term motivating
    doc 16
      freq 1
      pos 311
  term motivation
    doc 13
      freq 2
      pos 141
      pos 367
  term mount
    doc 5
      freq 2
      pos 3202
      pos 3588
    doc 10
      freq 3
      pos 9363
      pos 9371
      pos 9965
  term mountain
    doc 3
      freq 2
      pos 4966
      pos 4980
    doc 9
      freq 1
      pos 1773
  term move
    doc 7
      freq 1
      pos 276
    doc 12
      freq 2
      pos 2488
      pos 7666
    doc 15
      freq 1
      pos 3750
  term moved
    doc 12
      freq 1
      pos 6758
  term movement
    doc 15
      freq 1
      pos 2539
  term movie
    doc 13
      freq 3
      pos 3518
      pos 3561
      pos 3590
  term mp
    doc 10
      freq 1
      pos 12588
  term mpart01
    doc 11
      freq 1
      pos 3770
  term mpeg
    doc 6
      freq 10
      pos 209
      pos 447
      pos 557
      pos 564
      pos 1063
      pos 1239
      pos 2093
      pos 2634
      pos 2831
      pos 2991
  term mpls
    doc 1
      freq 52
      pos 123
      pos 162
      pos 459
      pos 579
      pos 734
      pos 853
      pos 871
      pos 879
      pos 898
      pos 920
      pos 931
      pos 942
      pos 951
      pos 1211
      pos 1220
      pos 1247
      pos 1260
      pos 1264
      pos 1273
      pos 1283
      pos 1299
      pos 1322
      pos 1336
      pos 1356
      pos 1383
      pos 1454
      pos 1485
      pos 1510
      pos 1540
      pos 1561
      pos 1779
      pos 1800
      pos 2010
      pos 6175
      pos 7444
      pos 7961
      pos 8007
      pos 8010
      pos 8013
      pos 8016
      pos 8033
      pos 8063
      pos 8073
      pos 8096
      pos 8133
      pos 8139
      pos 8219
      pos 8945
      pos 9043
      pos 9066
      pos 9092
      pos 9115
    doc 3
      freq 55
      pos 37
      pos 116
      pos 129
      pos 173
      pos 338
      pos 364
      pos 585
      pos 740
      pos 741
      pos 765
      pos 1044
      pos 1117
      pos 1285
      pos 1306
      pos 1430
      pos 1611
      pos 1783
      pos 2122
      pos 2241
      pos 2262
      pos 2433
      pos 2828
      pos 3212
      pos 3277
      pos 3332
      pos 3340
      pos 3369
      pos 3426
      pos 3501
      pos 3621
      pos 3822
      pos 3847
      pos 3877
      pos 4015
      pos 4041
      pos 4094
      pos 4113
      pos 4116
      pos 4127
      pos 4179
      pos 4214
      pos 4303
      pos 4330
      pos 4384
      pos 4564
      pos 4745
      pos 4838
      pos 4942
      pos 5007
      pos 5203
      pos 5497
      pos 5536
      pos 5593
      pos 5794
      pos 5950
    doc 8
      freq 10
      pos 126
      pos 481
      pos 491
      pos 671
      pos 1918
      pos 1955
      pos 1979
      pos 2003
      pos 2070
      pos 2121
  term mq0wcwydvqqkdarjrvrgmrwwggydvqqddbnhdgxhbnrhlmv4yw1wbguuy29tgge
    doc 10
      freq 1
      pos 6278
  term mqs3f8qvd3jy
    doc 10
      freq 1
      pos 12458
  term mr
    doc 6
      freq 3
      pos 1737
      pos 1776
      pos 1923
    doc 11
      freq 2
      pos 5141
      pos 5157
  term mrbvyc
    doc 10
      freq 1
      pos 6261
  term ms
    doc 1
      freq 2
      pos 9207
      pos 9239
    doc 10
      freq 1
      pos 13437
    doc 17
      freq 1
      pos 2375
  term msec
    doc 5
      freq 3
      pos 1953
      pos 3795
      pos 4011
  term msg
    doc 1
      freq 1
      pos 9420
  term msg01102
    doc 12
      freq 1
      pos 7655
  term msth5b
    doc 11
      freq 1
      pos 9990
  term msyqmknymhz38sa7yg
    doc 10
      freq 1
      pos 12765
  term mtu
    doc 1
      freq 3
      pos 2782
      pos 6136
      pos 6146
    doc 3
      freq 9
      pos 230
      pos 272
      pos 1608
      pos 2832
      pos 2895
      pos 4176
      pos 4186
      pos 4253
      pos 4274
    doc 4
      freq 13
      pos 350
      pos 1466
      pos 1590
      pos 1688
      pos 2147
      pos 2797
      pos 2813
      pos 2846
      pos 2883
      pos 2900
      pos 3058
      pos 3294
      pos 5355
    doc 8
      freq 1
      pos 1015
  term mtus
    doc 3
      freq 1
      pos 2852
  term much
    doc 0
      freq 1
      pos 16662
    doc 1
      freq 1
      pos 8718
    doc 2
      freq 1
      pos 3641
    doc 4
      freq 5
      pos 1441
      pos 2133
      pos 2799
      pos 3044
      pos 3280
    doc 10
      freq 3
      pos 655
      pos 7515
      pos 11143
    doc 11
      freq 2
      pos 4402
      pos 6580
    doc 12
      freq 9
      pos 4366
      pos 4630
      pos 4856
      pos 8106
      pos 8431
      pos 8465
      pos 8700
      pos 9285
      pos 9384
    doc 13
      freq 2
      pos 5458
      pos 6671
    doc 14
      freq 1
      pos 2862
    doc 15
      freq 2
      pos 2417
      pos 2981
    doc 16
      freq 1
      pos 365
    skipList 
      level 0
        skipDoc 13
        skipDocFP 1488725
        impacts 
          impact 
            freq 5
            norm 108
          impact 
            freq 9
            norm 113
        impactsEnd 
  term mukesh
    doc 4
      freq 1
      pos 6073
  term mukesh.gupt
    doc 4
      freq 1
      pos 6091
  term mule
    doc 11
      freq 1
      pos 9563
  term multi
    doc 2
      freq 1
      pos 2404
    doc 3
      freq 2
      pos 360
      pos 4689
    doc 5
      freq 2
      pos 2747
      pos 2839
    doc 15
      freq 1
      pos 3730
  term multi01
    doc 11
      freq 1
      pos 8121
  term multi01.98asdh
    doc 11
      freq 2
      pos 8146
      pos 8153
  term multi6
    doc 15
      freq 1
      pos 3778
  term multiaccess
    doc 0
      freq 5
      pos 5986
      pos 6038
      pos 6857
      pos 6950
      pos 7123
  term multiappend
    doc 16
      freq 3
      pos 290
      pos 557
      pos 2553
  term multicast
    doc 2
      freq 4
      pos 246
      pos 3006
      pos 3400
      pos 4203
    doc 4
      freq 20
      pos 1154
      pos 1668
      pos 1694
      pos 1736
      pos 1803
      pos 2942
      pos 2950
      pos 3911
      pos 4420
      pos 4428
      pos 4446
      pos 4463
      pos 4473
      pos 4479
      pos 4506
      pos 4512
      pos 4523
      pos 4526
      pos 4533
      pos 5807
    doc 5
      freq 13
      pos 99
      pos 166
      pos 239
      pos 361
      pos 463
      pos 479
      pos 514
      pos 557
      pos 2752
      pos 2779
      pos 3072
      pos 4201
      pos 4271
    doc 7
      freq 3
      pos 866
      pos 2276
      pos 2520
    doc 13
      freq 20
      pos 97
      pos 372
      pos 728
      pos 741
      pos 1767
      pos 1800
      pos 2247
      pos 2300
      pos 2362
      pos 2425
      pos 2521
      pos 2553
      pos 2672
      pos 2684
      pos 2702
      pos 2715
      pos 3921
      pos 4509
      pos 4529
      pos 6927
  term multihomed
    doc 12
      freq 1
      pos 7536
  term multihoming
    doc 15
      freq 3
      pos 463
      pos 855
      pos 3728
  term multilingual
    doc 17
      freq 1
      pos 1178
  term multimed
    doc 3
      freq 1
      pos 5752
    doc 5
      freq 7
      pos 177
      pos 199
      pos 529
      pos 592
      pos 2816
      pos 3595
      pos 4175
    doc 13
      freq 18
      pos 374
      pos 408
      pos 587
      pos 600
      pos 622
      pos 1009
      pos 1057
      pos 1286
      pos 1604
      pos 1906
      pos 1944
      pos 1983
      pos 1999
      pos 5214
      pos 5246
      pos 5662
      pos 5706
      pos 6800
  term multipart
    doc 7
      freq 2
      pos 2763
      pos 2766
    doc 10
      freq 1
      pos 5233
    doc 11
      freq 8
      pos 230
      pos 3539
      pos 3541
      pos 3695
      pos 3744
      pos 3749
      pos 3835
      pos 9508
    doc 16
      freq 3
      pos 1725
      pos 2019
      pos 2390
  term multiparts
    doc 7
      freq 1
      pos 2760
  term multiparty
    doc 13
      freq 2
      pos 1982
      pos 3245
  term multipath
    doc 0
      freq 1
      pos 11267
  term multipl
    doc 0
      freq 3
      pos 5388
      pos 10948
      pos 11264
    doc 2
      freq 3
      pos 1536
      pos 1892
      pos 2601
    doc 3
      freq 10
      pos 2254
      pos 3300
      pos 3975
      pos 3985
      pos 3991
      pos 3997
      pos 4432
      pos 4476
      pos 5542
      pos 5556
    doc 4
      freq 1
      pos 854
    doc 5
      freq 1
      pos 3417
    doc 6
      freq 4
      pos 1049
      pos 1527
      pos 2371
      pos 2728
    doc 10
      freq 6
      pos 1436
      pos 1723
      pos 2828
      pos 10447
      pos 10455
      pos 13036
    doc 11
      freq 10
      pos 304
      pos 447
      pos 456
      pos 1697
      pos 5549
      pos 5559
      pos 8075
      pos 8088
      pos 8233
      pos 8237
    doc 13
      freq 7
      pos 254
      pos 2270
      pos 2367
      pos 3707
      pos 3782
      pos 6570
      pos 6708
    doc 14
      freq 1
      pos 2535
    doc 15
      freq 12
      pos 217
      pos 226
      pos 477
      pos 481
      pos 859
      pos 875
      pos 1203
      pos 1209
      pos 1275
      pos 1891
      pos 2094
      pos 3704
    doc 16
      freq 1
      pos 295
    skipList 
      level 0
        skipDoc 11
        skipDocFP 1492582
        impacts 
          impact 
            freq 4
            norm 101
          impact 
            freq 10
            norm 107
        impactsEnd 
  term multiplayer
    doc 13
      freq 4
      pos 222
      pos 3235
      pos 3237
      pos 3281
  term multiplexed
    doc 1
      freq 1
      pos 152
  term multiplexing
    doc 1
      freq 2
      pos 568
      pos 659
    doc 3
      freq 1
      pos 1002
    doc 7
      freq 2
      pos 1034
      pos 2579
  term multiplied
    doc 0
      freq 1
      pos 6793
  term multipoint
    doc 1
      freq 3
      pos 977
      pos 979
      pos 1340
  term multiprotocol
    doc 3
      freq 1
      pos 4393
    doc 7
      freq 3
      pos 858
      pos 1186
      pos 2268
  term multipurpos
    doc 16
      freq 2
      pos 1082
      pos 2575
  term multitud
    doc 13
      freq 2
      pos 1878
      pos 2281
  term mumba
    doc 3
      freq 1
      pos 4805
  term mundy
    doc 0
      freq 1
      pos 17175
  term munich
    doc 5
      freq 2
      pos 4405
      pos 4419
  term must
    doc 0
      freq 54
      pos 954
      pos 955
      pos 2369
      pos 2451
      pos 2512
      pos 2572
      pos 2593
      pos 2645
      pos 2695
      pos 2758
      pos 2792
      pos 2840
      pos 2931
      pos 3015
      pos 3068
      pos 3158
      pos 3577
      pos 3609
      pos 3737
      pos 3812
      pos 3850
      pos 3868
      pos 4057
      pos 4125
      pos 4263
      pos 4312
      pos 4350
      pos 4368
      pos 4691
      pos 4983
      pos 5337
      pos 5458
      pos 5753
      pos 6101
      pos 6246
      pos 6326
      pos 10022
      pos 10089
      pos 10966
      pos 11176
      pos 11214
      pos 11232
      pos 12878
      pos 13132
      pos 13234
      pos 13451
      pos 13549
      pos 13641
      pos 13743
      pos 13816
      pos 13888
      pos 14028
      pos 14157
      pos 14370
    doc 1
      freq 58
      pos 617
      pos 685
      pos 874
      pos 1161
      pos 1162
      pos 1417
      pos 1434
      pos 1701
      pos 1734
      pos 1747
      pos 1760
      pos 1833
      pos 1842
      pos 2212
      pos 2263
      pos 2756
      pos 2820
      pos 3086
      pos 3159
      pos 3177
      pos 3199
      pos 3347
      pos 3435
      pos 3594
      pos 3796
      pos 3950
      pos 3969
      pos 4261
      pos 4270
      pos 4330
      pos 4654
      pos 4745
      pos 4815
      pos 4902
      pos 4946
      pos 5006
      pos 5617
      pos 5641
      pos 5980
      pos 6131
      pos 6209
      pos 6272
      pos 6312
      pos 6338
      pos 6410
      pos 6434
      pos 7317
      pos 7337
      pos 7356
      pos 7412
      pos 7728
      pos 8004
      pos 8047
      pos 8194
      pos 8481
      pos 8588
      pos 8636
      pos 8647
    doc 2
      freq 1
      pos 1823
    doc 3
      freq 37
      pos 1138
      pos 1169
      pos 1236
      pos 1237
      pos 1521
      pos 1750
      pos 1804
      pos 1883
      pos 1949
      pos 2031
      pos 2057
      pos 2096
      pos 2520
      pos 2552
      pos 2581
      pos 2764
      pos 2842
      pos 2904
      pos 3015
      pos 3089
      pos 3117
      pos 3182
      pos 3348
      pos 3555
      pos 3574
      pos 3682
      pos 3704
      pos 3712
      pos 3861
      pos 3911
      pos 4181
      pos 4282
      pos 4287
      pos 5312
      pos 5327
      pos 5415
      pos 5658
    doc 4
      freq 29
      pos 445
      pos 446
      pos 521
      pos 1097
      pos 1131
      pos 1182
      pos 1348
      pos 1390
      pos 1427
      pos 1438
      pos 1635
      pos 1840
      pos 2213
      pos 2267
      pos 2549
      pos 2736
      pos 2861
      pos 2980
      pos 3100
      pos 3138
      pos 3216
      pos 3405
      pos 3521
      pos 3663
      pos 3829
      pos 3881
      pos 3924
      pos 3950
      pos 3968
    doc 5
      freq 14
      pos 900
      pos 1049
      pos 1050
      pos 1649
      pos 3135
      pos 3225
      pos 3250
      pos 3373
      pos 3494
      pos 3504
      pos 3517
      pos 3546
      pos 3855
      pos 3884
    doc 6
      freq 4
      pos 1308
      pos 1397
      pos 1474
      pos 1502
    doc 8
      freq 8
      pos 283
      pos 309
      pos 310
      pos 372
      pos 446
      pos 932
      pos 1257
      pos 1452
    doc 9
      freq 14
      pos 346
      pos 347
      pos 459
      pos 754
      pos 776
      pos 806
      pos 899
      pos 963
      pos 1038
      pos 1071
      pos 1089
      pos 1149
      pos 1168
      pos 1243
    doc 10
      freq 83
      pos 579
      pos 677
      pos 678
      pos 2134
      pos 2148
      pos 2244
      pos 2275
      pos 2344
      pos 2391
      pos 2488
      pos 2525
      pos 2554
      pos 2774
      pos 2926
      pos 3090
      pos 3166
      pos 3267
      pos 3303
      pos 3332
      pos 3383
      pos 3642
      pos 3894
      pos 3915
      pos 3929
      pos 4062
      pos 4108
      pos 4144
      pos 4155
      pos 4194
      pos 4241
      pos 4248
      pos 4271
      pos 4280
      pos 4378
      pos 4421
      pos 4447
      pos 4534
      pos 4747
      pos 4887
      pos 5035
      pos 5128
      pos 5136
      pos 5157
      pos 5184
      pos 5348
      pos 5361
      pos 5375
      pos 5412
      pos 5463
      pos 5482
      pos 5504
      pos 5542
      pos 5574
      pos 5595
      pos 5614
      pos 5629
      pos 5729
      pos 5934
      pos 5984
      pos 6025
      pos 7874
      pos 8166
      pos 8494
      pos 8514
      pos 8528
      pos 8542
      pos 9210
      pos 9237
      pos 10347
      pos 10380
      pos 10544
      pos 10686
      pos 10741
      pos 11339
      pos 11973
      pos 12056
      pos 12866
      pos 12901
      pos 12924
      pos 12945
      pos 12982
      pos 13002
      pos 13028
    doc 11
      freq 38
      pos 1412
      pos 2120
      pos 2133
      pos 2148
      pos 2320
      pos 2325
      pos 3265
      pos 3581
      pos 3717
      pos 3727
      pos 3973
      pos 4092
      pos 4636
      pos 5299
      pos 5603
      pos 5769
      pos 5899
      pos 5913
      pos 6281
      pos 6292
      pos 6406
      pos 6557
      pos 7048
      pos 7186
      pos 7295
      pos 7441
      pos 7583
      pos 7807
      pos 7915
      pos 8103
      pos 8401
      pos 8665
      pos 8683
      pos 8696
      pos 8793
      pos 8898
      pos 8976
      pos 9328
    doc 12
      freq 15
      pos 937
      pos 1212
      pos 2216
      pos 2936
      pos 4128
      pos 4649
      pos 4689
      pos 4743
      pos 5666
      pos 5790
      pos 5842
      pos 6018
      pos 7995
      pos 8015
      pos 8131
    doc 13
      freq 36
      pos 1037
      pos 1185
      pos 1186
      pos 3652
      pos 3715
      pos 3827
      pos 3980
      pos 4051
      pos 4072
      pos 4206
      pos 4278
      pos 4380
      pos 4749
      pos 5051
      pos 5135
      pos 5192
      pos 5280
      pos 5394
      pos 5490
      pos 5816
      pos 5833
      pos 5859
      pos 5873
      pos 5899
      pos 5925
      pos 5967
      pos 5982
      pos 6060
      pos 6082
      pos 6202
      pos 6216
      pos 6237
      pos 6256
      pos 6269
      pos 6551
      pos 6635
    doc 14
      freq 5
      pos 354
      pos 1939
      pos 2484
      pos 3558
      pos 4526
    doc 17
      freq 9
      pos 269
      pos 270
      pos 715
      pos 736
      pos 1356
      pos 1373
      pos 1452
      pos 1855
      pos 1883
    doc 18
      freq 10
      pos 344
      pos 384
      pos 385
      pos 609
      pos 800
      pos 862
      pos 1045
      pos 1111
      pos 1152
      pos 1185
    skipList 
      level 0
        skipDoc 8
        skipDocFP 1494883
        impacts 
          impact 
            freq 8
            norm 97
          impact 
            freq 14
            norm 104
          impact 
            freq 37
            norm 107
          impact 
            freq 58
            norm 113
        impactsEnd 
        skipDoc 18
        skipDocFP 1498150
        impacts 
          impact 
            freq 14
            norm 95
          impact 
            freq 36
            norm 109
          impact 
            freq 38
            norm 114
          impact 
            freq 83
            norm 116
        impactsEnd 
  term mutual
    doc 5
      freq 1
      pos 2988
    doc 10
      freq 2
      pos 1377
      pos 1518
  term mve
    doc 11
      freq 1
      pos 10196
  term mvf2pvv7ddmz
    doc 10
      freq 1
      pos 12788
  term mvzq690qpytveetxge5mqq2qej562v1ex4ganp64qw7cshdmoqdxvkhdc
    doc 11
      freq 1
      pos 10242
  term mx
    doc 12
      freq 4
      pos 2163
      pos 2834
      pos 2907
      pos 8380
  term mx8iipscgpqltyseunvjbxcv72xy
    doc 11
      freq 1
      pos 10447
  term my
    doc 10
      freq 2
      pos 7937
      pos 12396
    doc 11
      freq 1
      pos 9801
  term myweq2utmgsyxkxsfybb18tcowcty0ndbr24zyojf2nbzs98lz
    doc 10
      freq 1
      pos 6851
  term n
    doc 0
      freq 1
      pos 12157
    doc 1
      freq 14
      pos 18
      pos 7509
      pos 7511
      pos 7576
      pos 7580
      pos 7598
      pos 8917
      pos 9054
      pos 9104
      pos 9371
      pos 9418
      pos 9427
      pos 9432
      pos 9438
    doc 2
      freq 1
      pos 3333
    doc 3
      freq 5
      pos 18
      pos 4360
      pos 4615
      pos 4648
      pos 4861
    doc 4
      freq 3
      pos 1904
      pos 1906
      pos 2032
    doc 8
      freq 6
      pos 675
      pos 684
      pos 1792
      pos 1851
      pos 1943
      pos 1991
    doc 10
      freq 2
      pos 6886
      pos 11535
    doc 11
      freq 6
      pos 2240
      pos 10119
      pos 10128
      pos 10202
      pos 10436
      pos 10455
    doc 14
      freq 57
      pos 583
      pos 589
      pos 593
      pos 597
      pos 601
      pos 605
      pos 608
      pos 612
      pos 615
      pos 630
      pos 695
      pos 698
      pos 711
      pos 731
      pos 752
      pos 790
      pos 875
      pos 895
      pos 910
      pos 913
      pos 927
      pos 950
      pos 1073
      pos 1091
      pos 1196
      pos 1247
      pos 1288
      pos 1334
      pos 1346
      pos 1389
      pos 1392
      pos 1415
      pos 1443
      pos 1471
      pos 1495
      pos 1566
      pos 1569
      pos 1592
      pos 1619
      pos 1772
      pos 1775
      pos 3219
      pos 3825
      pos 4174
      pos 4194
      pos 4240
      pos 4261
      pos 4317
      pos 4386
      pos 4447
      pos 4478
      pos 4538
      pos 4559
      pos 4617
      pos 4871
      pos 5199
      pos 5272
    doc 16
      freq 2
      pos 2571
      pos 2573
    skipList 
      level 0
        skipDoc 11
        skipDocFP 1502851
        impacts 
          impact 
            freq 6
            norm 97
          impact 
            freq 14
            norm 113
        impactsEnd 
  term n4ci
    doc 10
      freq 1
      pos 12819
  term n7ciscnrdbx901otygirg
    doc 10
      freq 1
      pos 12586
  term n7dpkl6hgxmfimuzkvmmcjnkeinf6lnku9nitmuhxnzm7vzfwt8fuaxxl
    doc 11
      freq 1
      pos 10397
  term n8q7oyfs1eqmefsqjw1oofhmaoqncmjluerlmesox20
    doc 10
      freq 1
      pos 12542
  term n9ypgf7fhp8j
    doc 10
      freq 1
      pos 12547
  term nack
    doc 13
      freq 1
      pos 2289
  term nadeau
    doc 3
      freq 3
      pos 4538
      pos 4596
      pos 4662
    doc 8
      freq 1
      pos 1813
  term nagi
    doc 0
      freq 1
      pos 15921
  term nakahar
    doc 13
      freq 1
      pos 6998
  term name
    doc 1
      freq 7
      pos 379
      pos 7761
      pos 7764
      pos 7811
      pos 7814
      pos 7899
      pos 7917
    doc 4
      freq 1
      pos 4773
    doc 8
      freq 4
      pos 607
      pos 985
      pos 1279
      pos 1474
    doc 10
      freq 28
      pos 3040
      pos 3058
      pos 3081
      pos 3110
      pos 3114
      pos 3129
      pos 6127
      pos 8656
      pos 9574
      pos 9616
      pos 9634
      pos 9646
      pos 9666
      pos 9683
      pos 9730
      pos 9760
      pos 9765
      pos 9839
      pos 9905
      pos 9976
      pos 10399
      pos 10565
      pos 10614
      pos 10667
      pos 11524
      pos 11530
      pos 11976
      pos 12059
    doc 11
      freq 31
      pos 180
      pos 288
      pos 340
      pos 357
      pos 951
      pos 959
      pos 968
      pos 1062
      pos 1066
      pos 1141
      pos 1273
      pos 1314
      pos 1685
      pos 1688
      pos 1723
      pos 1845
      pos 2080
      pos 2459
      pos 2613
      pos 2638
      pos 2743
      pos 2805
      pos 2828
      pos 2860
      pos 2894
      pos 2909
      pos 5082
      pos 5094
      pos 6256
      pos 6284
      pos 6494
    doc 12
      freq 43
      pos 75
      pos 172
      pos 610
      pos 889
      pos 1031
      pos 1085
      pos 1092
      pos 1384
      pos 1754
      pos 1771
      pos 2270
      pos 2330
      pos 2348
      pos 2394
      pos 2440
      pos 2495
      pos 2685
      pos 2818
      pos 3988
      pos 4022
      pos 4275
      pos 4288
      pos 4315
      pos 4325
      pos 4344
      pos 4668
      pos 4736
      pos 5066
      pos 5082
      pos 5097
      pos 5304
      pos 5338
      pos 5357
      pos 5413
      pos 5958
      pos 5969
      pos 6597
      pos 7026
      pos 7114
      pos 7218
      pos 7245
      pos 7965
      pos 8258
    doc 14
      freq 105
      pos 19
      pos 85
      pos 100
      pos 139
      pos 146
      pos 157
      pos 164
      pos 199
      pos 218
      pos 327
      pos 353
      pos 385
      pos 446
      pos 452
      pos 458
      pos 506
      pos 515
      pos 531
      pos 561
      pos 587
      pos 666
      pos 690
      pos 705
      pos 845
      pos 905
      pos 924
      pos 959
      pos 1081
      pos 1096
      pos 1100
      pos 1109
      pos 1138
      pos 1151
      pos 1157
      pos 1206
      pos 1222
      pos 1356
      pos 1369
      pos 1378
      pos 1384
      pos 1402
      pos 1424
      pos 1475
      pos 1551
      pos 1561
      pos 1579
      pos 1601
      pos 1755
      pos 1779
      pos 1789
      pos 1797
      pos 1829
      pos 1872
      pos 1915
      pos 2054
      pos 2162
      pos 2238
      pos 2309
      pos 2322
      pos 2339
      pos 2353
      pos 2366
      pos 2406
      pos 2419
      pos 2464
      pos 2494
      pos 2553
      pos 2892
      pos 2907
      pos 3237
      pos 3260
      pos 3544
      pos 3553
      pos 3842
      pos 3851
      pos 3855
      pos 3866
      pos 4138
      pos 4163
      pos 4172
      pos 4224
      pos 4233
      pos 4238
      pos 4289
      pos 4298
      pos 4303
      pos 4411
      pos 4420
      pos 4425
      pos 4505
      pos 4514
      pos 4519
      pos 4587
      pos 4596
      pos 4612
      pos 4965
      pos 4974
      pos 5029
      pos 5033
      pos 5044
      pos 5147
      pos 5180
      pos 5193
      pos 5459
      pos 5552
    doc 15
      freq 2
      pos 1954
      pos 3080
    doc 16
      freq 4
      pos 546
      pos 930
      pos 941
      pos 965
    doc 17
      freq 5
      pos 1136
      pos 1720
      pos 1741
      pos 1785
      pos 1837
    doc 18
      freq 44
      pos 125
      pos 195
      pos 211
      pos 214
      pos 218
      pos 235
      pos 238
      pos 608
      pos 630
      pos 643
      pos 649
      pos 657
      pos 663
      pos 691
      pos 697
      pos 726
      pos 739
      pos 753
      pos 770
      pos 780
      pos 784
      pos 793
      pos 950
      pos 981
      pos 997
      pos 1077
      pos 1089
      pos 1092
      pos 1098
      pos 1105
      pos 1276
      pos 1280
      pos 1295
      pos 1368
      pos 1573
      pos 1579
      pos 1629
      pos 1632
      pos 1824
      pos 1831
      pos 1850
      pos 1856
      pos 1936
      pos 1956
    skipList 
      level 0
        skipDoc 15
        skipDocFP 1505412
        impacts 
          impact 
            freq 4
            norm 97
          impact 
            freq 105
            norm 107
        impactsEnd 
  term name's
    doc 18
      freq 1
      pos 1107
  term name:john_smith
    doc 11
      freq 1
      pos 7669
  term named
    doc 2
      freq 1
      pos 5209
    doc 12
      freq 2
      pos 2151
      pos 2310
    doc 17
      freq 1
      pos 305
  term namedroppers
    doc 12
      freq 2
      pos 7652
      pos 7653
  term namely
    doc 5
      freq 3
      pos 2899
      pos 3065
      pos 3644
  term names
    doc 10
      freq 13
      pos 280
      pos 295
      pos 312
      pos 3070
      pos 6140
      pos 9558
      pos 9704
      pos 9807
      pos 9859
      pos 9914
      pos 9956
      pos 10365
      pos 11481
    doc 11
      freq 5
      pos 2748
      pos 2760
      pos 6503
      pos 8721
      pos 8811
    doc 12
      freq 17
      pos 257
      pos 261
      pos 269
      pos 592
      pos 1959
      pos 1990
      pos 1994
      pos 2118
      pos 2122
      pos 2225
      pos 2242
      pos 2291
      pos 2486
      pos 3266
      pos 4224
      pos 6741
      pos 7001
    doc 14
      freq 23
      pos 112
      pos 332
      pos 340
      pos 368
      pos 494
      pos 1134
      pos 1260
      pos 1301
      pos 1896
      pos 2074
      pos 2103
      pos 2137
      pos 2178
      pos 2262
      pos 2292
      pos 2532
      pos 2661
      pos 2755
      pos 2846
      pos 4980
      pos 5153
      pos 5366
      pos 5380
    doc 15
      freq 1
      pos 2057
    doc 17
      freq 1
      pos 1114
    doc 18
      freq 22
      pos 109
      pos 202
      pos 231
      pos 266
      pos 314
      pos 332
      pos 560
      pos 583
      pos 634
      pos 831
      pos 850
      pos 867
      pos 881
      pos 893
      pos 1051
      pos 1062
      pos 1217
      pos 1238
      pos 1607
      pos 1624
      pos 1877
      pos 1894
  term nameservers
    doc 12
      freq 1
      pos 9132
  term naming
    doc 12
      freq 2
      pos 99
      pos 2298
  term naptr
    doc 10
      freq 1
      pos 10599
  term narasimhan
    doc 11
      freq 1
      pos 9442
  term narrow
    doc 0
      freq 3
      pos 1877
      pos 5163
      pos 5193
  term narten
    doc 4
      freq 2
      pos 5194
      pos 5479
    doc 5
      freq 1
      pos 4142
    doc 8
      freq 1
      pos 1726
    doc 12
      freq 3
      pos 6825
      pos 7077
      pos 7124
    doc 15
      freq 1
      pos 3914
  term naslund
    doc 5
      freq 2
      pos 4169
      pos 4358
  term nasser
    doc 1
      freq 1
      pos 9522
    doc 3
      freq 1
      pos 5887
  term nat
    doc 12
      freq 7
      pos 414
      pos 1605
      pos 6519
      pos 6529
      pos 6561
      pos 7482
      pos 7667
  term national
    doc 1
      freq 1
      pos 9123
  term nativ
    doc 1
      freq 4
      pos 1048
      pos 1050
      pos 2036
      pos 8058
    doc 3
      freq 6
      pos 629
      pos 632
      pos 967
      pos 1326
      pos 1355
      pos 3083
  term nats
    doc 12
      freq 1
      pos 7619
  term natur
    doc 0
      freq 1
      pos 10300
    doc 10
      freq 3
      pos 3102
      pos 8904
      pos 10249
  term natural
    doc 17
      freq 1
      pos 1609
  term naturally
    doc 12
      freq 1
      pos 5354
    doc 15
      freq 1
      pos 1540
    doc 17
      freq 1
      pos 1602
  term naur
    doc 16
      freq 1
      pos 1420
  term naus
    doc 7
      freq 2
      pos 1028
      pos 2573
  term navi
    doc 3
      freq 1
      pos 4804
  term nayfz
    doc 10
      freq 1
      pos 12598
  term nbih8yt6cbs0q2sdycyeksl9k75nmkmn7ebwde2wlm3646jp2q7ftu2btq496egc
    doc 10
      freq 1
      pos 12758
  term nbkonvbq3oksgxoywmx2cdqdfodbs9
    doc 11
      freq 1
      pos 10059
  term ncl
    doc 11
      freq 2
      pos 4662
      pos 4681
  term ncoxalyvraom
    doc 11
      freq 1
      pos 10333
  term ncp
    doc 0
      freq 1
      pos 7991
  term nd9boe88uwjbanbrspd4bms
    doc 10
      freq 1
      pos 6854
  term nda2ndaynlowvzelmakga1uebhmcvvmxczajbgnvbagmak1tmq8wdqydvqqhdazc
    doc 10
      freq 1
      pos 6883
  term ndaksdj9342dasdd
    doc 11
      freq 1
      pos 9087
  term ndsgjstdilar
    doc 11
      freq 1
      pos 10255
  term ndss
    doc 5
      freq 1
      pos 4281
  term neal
    doc 0
      freq 1
      pos 15913
  term near
    doc 4
      freq 2
      pos 4509
      pos 4685
  term nearby
    doc 18
      freq 1
      pos 892
  term nearly
    doc 14
      freq 1
      pos 2876
  term necessarily
    doc 12
      freq 2
      pos 1183
      pos 5633
    doc 15
      freq 1
      pos 3868
    doc 17
      freq 1
      pos 358
    doc 18
      freq 1
      pos 1162
  term necessary
    doc 0
      freq 1
      pos 2152
    doc 1
      freq 5
      pos 903
      pos 1305
      pos 1904
      pos 3991
      pos 6002
    doc 2
      freq 3
      pos 2036
      pos 5556
      pos 6069
    doc 3
      freq 5
      pos 1111
      pos 1971
      pos 2162
      pos 3247
      pos 3358
    doc 4
      freq 1
      pos 1625
    doc 5
      freq 4
      pos 369
      pos 549
      pos 2855
      pos 3118
    doc 6
      freq 2
      pos 1010
      pos 1633
    doc 7
      freq 1
      pos 1219
    doc 9
      freq 2
      pos 1196
      pos 1562
    doc 10
      freq 5
      pos 556
      pos 8263
      pos 8341
      pos 9010
      pos 11235
    doc 12
      freq 1
      pos 8848
    doc 13
      freq 3
      pos 1855
      pos 1988
      pos 4819
    doc 14
      freq 2
      pos 1255
      pos 1296
    doc 15
      freq 1
      pos 1795
    doc 16
      freq 1
      pos 464
    doc 17
      freq 1
      pos 1988
    skipList 
      level 0
        skipDoc 7
        skipDocFP 1514605
        impacts 
          impact 
            freq 1
            norm 100
          impact 
            freq 2
            norm 101
          impact 
            freq 4
            norm 104
          impact 
            freq 5
            norm 107
        impactsEnd 
        skipDoc 17
        skipDocFP 1515116
        impacts 
          impact 
            freq 2
            norm 95
          impact 
            freq 3
            norm 109
          impact 
            freq 5
            norm 116
        impactsEnd 
  term necessity
    doc 5
      freq 1
      pos 2463
  term need
    doc 0
      freq 9
      pos 1556
      pos 1564
      pos 3615
      pos 4131
      pos 6115
      pos 6555
      pos 10972
      pos 13362
      pos 13378
    doc 1
      freq 2
      pos 536
      pos 3788
    doc 2
      freq 3
      pos 645
      pos 4123
      pos 4188
    doc 3
      freq 2
      pos 2747
      pos 5235
    doc 5
      freq 6
      pos 1089
      pos 1185
      pos 1493
      pos 2582
      pos 2968
      pos 3751
    doc 6
      freq 3
      pos 453
      pos 796
      pos 1641
    doc 7
      freq 1
      pos 1722
    doc 9
      freq 1
      pos 310
    doc 10
      freq 2
      pos 5023
      pos 10837
    doc 12
      freq 6
      pos 1526
      pos 5146
      pos 6103
      pos 6326
      pos 8681
      pos 8838
    doc 13
      freq 10
      pos 694
      pos 770
      pos 979
      pos 4102
      pos 4244
      pos 4844
      pos 5218
      pos 5263
      pos 5362
      pos 5794
    doc 15
      freq 8
      pos 605
      pos 1170
      pos 1584
      pos 2442
      pos 2709
      pos 2773
      pos 3200
      pos 3266
    doc 16
      freq 1
      pos 1761
    doc 17
      freq 1
      pos 579
    doc 18
      freq 1
      pos 851
    skipList 
      level 0
        skipDoc 9
        skipDocFP 1516209
        impacts 
          impact 
            freq 1
            norm 95
          impact 
            freq 3
            norm 101
          impact 
            freq 6
            norm 104
          impact 
            freq 9
            norm 120
        impactsEnd 
  term needed
    doc 1
      freq 3
      pos 822
      pos 1912
      pos 7938
    doc 2
      freq 2
      pos 1202
      pos 1869
    doc 3
      freq 1
      pos 3483
    doc 6
      freq 2
      pos 921
      pos 2526
    doc 11
      freq 1
      pos 868
    doc 12
      freq 2
      pos 1551
      pos 6725
    doc 13
      freq 5
      pos 715
      pos 1311
      pos 2228
      pos 3853
      pos 5317
    doc 15
      freq 3
      pos 2036
      pos 2509
      pos 3578
    doc 16
      freq 1
      pos 1165
    doc 18
      freq 1
      pos 745
    skipList 
      level 0
        skipDoc 15
        skipDocFP 1517749
        impacts 
          impact 
            freq 2
            norm 101
          impact 
            freq 3
            norm 104
          impact 
            freq 5
            norm 109
        impactsEnd 
  term needlessly
    doc 10
      freq 1
      pos 3965
  term needs
    doc 1
      freq 5
      pos 1586
      pos 1618
      pos 1644
      pos 2966
      pos 4739
    doc 2
      freq 1
      pos 3842
    doc 5
      freq 7
      pos 517
      pos 537
      pos 1031
      pos 1696
      pos 2168
      pos 2315
      pos 3148
    doc 9
      freq 2
      pos 428
      pos 558
    doc 10
      freq 1
      pos 1303
    doc 11
      freq 1
      pos 5127
    doc 12
      freq 1
      pos 4836
    doc 13
      freq 8
      pos 719
      pos 735
      pos 2209
      pos 4351
      pos 4874
      pos 5808
      pos 6521
      pos 6542
    doc 15
      freq 5
      pos 902
      pos 1242
      pos 1434
      pos 2617
      pos 3507
    skipList 
      level 0
        skipDoc 13
        skipDocFP 1518649
        impacts 
          impact 
            freq 2
            norm 95
          impact 
            freq 7
            norm 104
          impact 
            freq 8
            norm 109
        impactsEnd 
  term negat
    doc 17
      freq 1
      pos 1612
  term negates
    doc 14
      freq 1
      pos 2861
  term negativ
    doc 0
      freq 1
      pos 16155
    doc 5
      freq 4
      pos 1267
      pos 1309
      pos 1362
      pos 1435
    doc 11
      freq 4
      pos 262
      pos 4525
      pos 4532
      pos 4630
    doc 12
      freq 2
      pos 1714
      pos 1801
  term negotiat
    doc 1
      freq 1
      pos 5620
  term negotiated
    doc 0
      freq 1
      pos 6643
    doc 2
      freq 1
      pos 788
    doc 5
      freq 2
      pos 1791
      pos 1879
  term negotiation
    doc 1
      freq 4
      pos 308
      pos 4913
      pos 5606
      pos 5922
    doc 13
      freq 2
      pos 1970
      pos 6822
  term neighbor
    doc 0
      freq 7
      pos 9164
      pos 9515
      pos 9550
      pos 9747
      pos 9773
      pos 9935
      pos 10295
    doc 4
      freq 2
      pos 372
      pos 5201
    doc 12
      freq 1
      pos 7776
  term neighboring
    doc 0
      freq 16
      pos 770
      pos 788
      pos 807
      pos 9065
      pos 9109
      pos 9134
      pos 9302
      pos 9386
      pos 9417
      pos 9465
      pos 9572
      pos 9616
      pos 9648
      pos 9809
      pos 9841
      pos 9872
  term neighbors
    doc 0
      freq 1
      pos 1758
    doc 1
      freq 1
      pos 8743
  term neighboursnpaaddress
    doc 0
      freq 1
      pos 9069
  term neighboursystemids
    doc 0
      freq 1
      pos 9139
  term neighboursystemtyp
    doc 0
      freq 1
      pos 9113
  term neil
    doc 11
      freq 1
      pos 9526
  term neither
    doc 1
      freq 1
      pos 974
    doc 10
      freq 1
      pos 1660
    doc 14
      freq 1
      pos 2226
  term nepean
    doc 3
      freq 1
      pos 4877
  term net
    doc 1
      freq 1
      pos 9538
    doc 3
      freq 1
      pos 5903
  term netapp.com
    doc 1
      freq 1
      pos 9589
  term netlab.tkk.f
    doc 13
      freq 1
      pos 7056
  term netmask
    doc 0
      freq 3
      pos 3786
      pos 4298
      pos 11163
  term network
    doc 0
      freq 51
      pos 0
      pos 103
      pos 246
      pos 586
      pos 1416
      pos 1423
      pos 1450
      pos 1663
      pos 2413
      pos 5300
      pos 5987
      pos 6039
      pos 6161
      pos 9351
      pos 10835
      pos 10938
      pos 11123
      pos 11375
      pos 12015
      pos 13122
      pos 13224
      pos 13316
      pos 13441
      pos 13527
      pos 13631
      pos 13721
      pos 15991
      pos 16010
      pos 16015
      pos 16028
      pos 16049
      pos 16058
      pos 16065
      pos 16125
      pos 16158
      pos 16226
      pos 16307
      pos 16350
      pos 16353
      pos 16390
      pos 16429
      pos 16445
      pos 16459
      pos 16527
      pos 16535
      pos 16760
      pos 16781
      pos 16909
      pos 16936
      pos 17027
      pos 17122
    doc 1
      freq 24
      pos 0
      pos 27
      pos 164
      pos 461
      pos 543
      pos 581
      pos 594
      pos 1213
      pos 1311
      pos 6177
      pos 7446
      pos 7490
      pos 7520
      pos 8065
      pos 8075
      pos 8100
      pos 8127
      pos 8135
      pos 8221
      pos 8603
      pos 8613
      pos 9128
      pos 9138
      pos 9574
    doc 2
      freq 7
      pos 0
      pos 74
      pos 1234
      pos 2491
      pos 2512
      pos 3690
      pos 3733
    doc 3
      freq 17
      pos 0
      pos 117
      pos 366
      pos 381
      pos 1118
      pos 1288
      pos 1309
      pos 1624
      pos 3151
      pos 3427
      pos 3502
      pos 4706
      pos 5477
      pos 5498
      pos 5549
      pos 5765
      pos 5843
    doc 4
      freq 4
      pos 0
      pos 4656
      pos 4723
      pos 4732
    doc 5
      freq 3
      pos 0
      pos 4275
      pos 4290
    doc 6
      freq 30
      pos 0
      pos 200
      pos 365
      pos 379
      pos 391
      pos 658
      pos 684
      pos 806
      pos 848
      pos 867
      pos 946
      pos 978
      pos 1015
      pos 1094
      pos 1499
      pos 1630
      pos 1678
      pos 1686
      pos 2437
      pos 2448
      pos 2498
      pos 2513
      pos 2542
      pos 2567
      pos 2658
      pos 2733
      pos 2746
      pos 2783
      pos 2801
      pos 2959
    doc 7
      freq 10
      pos 0
      pos 883
      pos 980
      pos 1906
      pos 2045
      pos 2116
      pos 2328
      pos 2347
      pos 2414
      pos 2432
    doc 8
      freq 3
      pos 0
      pos 1697
      pos 2031
    doc 9
      freq 2
      pos 0
      pos 653
    doc 10
      freq 9
      pos 0
      pos 611
      pos 666
      pos 1513
      pos 8116
      pos 8122
      pos 8136
      pos 8144
      pos 12911
    doc 11
      freq 1
      pos 0
    doc 12
      freq 7
      pos 0
      pos 1602
      pos 2408
      pos 5002
      pos 7399
      pos 7477
      pos 7616
    doc 13
      freq 8
      pos 0
      pos 791
      pos 1811
      pos 2640
      pos 3444
      pos 4080
      pos 4364
      pos 5158
    doc 14
      freq 1
      pos 0
    doc 15
      freq 5
      pos 0
      pos 1992
      pos 3741
      pos 3755
      pos 3760
    doc 16
      freq 1
      pos 0
    doc 17
      freq 1
      pos 0
    doc 18
      freq 1
      pos 0
    skipList 
      level 0
        skipDoc 7
        skipDocFP 1521674
        impacts 
          impact 
            freq 10
            norm 100
          impact 
            freq 30
            norm 101
          impact 
            freq 51
            norm 120
        impactsEnd 
        skipDoc 15
        skipDocFP 1524038
        impacts 
          impact 
            freq 2
            norm 95
          impact 
            freq 3
            norm 97
          impact 
            freq 5
            norm 104
          impact 
            freq 8
            norm 109
          impact 
            freq 9
            norm 116
        impactsEnd 
  term networked
    doc 13
      freq 1
      pos 637
  term networking
    doc 1
      freq 1
      pos 157
    doc 3
      freq 1
      pos 1223
    doc 13
      freq 1
      pos 7045
  term networks
    doc 0
      freq 12
      pos 11
      pos 137
      pos 335
      pos 1150
      pos 2923
      pos 6858
      pos 6951
      pos 7124
      pos 10903
      pos 16081
      pos 16243
      pos 16617
    doc 1
      freq 10
      pos 8060
      pos 8154
      pos 9044
      pos 9067
      pos 9093
      pos 9116
      pos 9189
      pos 9300
      pos 9314
      pos 9369
    doc 2
      freq 9
      pos 2488
      pos 2509
      pos 2538
      pos 2564
      pos 2572
      pos 2594
      pos 2635
      pos 2714
      pos 3432
    doc 3
      freq 12
      pos 38
      pos 130
      pos 4425
      pos 4459
      pos 4464
      pos 4815
      pos 4859
      pos 4873
      pos 4888
      pos 4948
      pos 4962
      pos 4976
    doc 4
      freq 2
      pos 25
      pos 6077
    doc 6
      freq 11
      pos 265
      pos 324
      pos 353
      pos 422
      pos 466
      pos 487
      pos 501
      pos 518
      pos 551
      pos 836
      pos 3002
    doc 7
      freq 4
      pos 693
      pos 872
      pos 1989
      pos 2282
    doc 8
      freq 4
      pos 1919
      pos 1956
      pos 1980
      pos 2004
    doc 10
      freq 1
      pos 13307
    doc 11
      freq 2
      pos 17
      pos 10538
    doc 12
      freq 6
      pos 3372
      pos 4100
      pos 4127
      pos 5629
      pos 7537
      pos 7602
    doc 13
      freq 6
      pos 549
      pos 948
      pos 970
      pos 1022
      pos 4497
      pos 5097
    doc 15
      freq 2
      pos 478
      pos 3561
    skipList 
      level 0
        skipDoc 8
        skipDocFP 1525708
        impacts 
          impact 
            freq 4
            norm 97
          impact 
            freq 11
            norm 101
          impact 
            freq 12
            norm 107
        impactsEnd 
  term neustar
    doc 10
      freq 2
      pos 9
      pos 13407
  term neustar.biz
    doc 10
      freq 1
      pos 13425
  term never
    doc 0
      freq 2
      pos 6169
      pos 9360
    doc 1
      freq 1
      pos 1304
    doc 3
      freq 1
      pos 2495
    doc 7
      freq 1
      pos 209
    doc 10
      freq 1
      pos 8566
    doc 11
      freq 2
      pos 2101
      pos 7454
    doc 12
      freq 3
      pos 1299
      pos 1793
      pos 8252
    doc 14
      freq 1
      pos 1211
    skipList 
      level 0
        skipDoc 14
        skipDocFP 1527633
        impacts 
          impact 
            freq 1
            norm 100
          impact 
            freq 3
            norm 113
        impactsEnd 
  term nevertheless
    doc 1
      freq 1
      pos 8831
    doc 7
      freq 1
      pos 1383
  term new
    doc 0
      freq 4
      pos 2137
      pos 5260
      pos 5272
      pos 14239
    doc 1
      freq 10
      pos 754
      pos 2145
      pos 2273
      pos 2281
      pos 2315
      pos 2338
      pos 2432
      pos 7751
      pos 7801
      pos 7905
    doc 2
      freq 17
      pos 130
      pos 390
      pos 978
      pos 1009
      pos 1042
      pos 1049
      pos 1096
      pos 1483
      pos 1495
      pos 1502
      pos 2144
      pos 3960
      pos 4701
      pos 4718
      pos 4751
      pos 4971
      pos 6165
    doc 4
      freq 14
      pos 245
      pos 945
      pos 952
      pos 961
      pos 4747
      pos 4810
      pos 4965
      pos 5006
      pos 5030
      pos 5047
      pos 5098
      pos 5125
      pos 5857
      pos 5906
    doc 5
      freq 4
      pos 2587
      pos 2681
      pos 3756
      pos 3923
    doc 7
      freq 5
      pos 575
      pos 1372
      pos 1530
      pos 1660
      pos 1674
    doc 8
      freq 1
      pos 198
    doc 9
      freq 2
      pos 1433
      pos 1439
    doc 10
      freq 20
      pos 139
      pos 1564
      pos 1942
      pos 2102
      pos 3798
      pos 4509
      pos 4769
      pos 5688
      pos 5694
      pos 8918
      pos 11469
      pos 11486
      pos 11559
      pos 11647
      pos 11741
      pos 11854
      pos 11935
      pos 11989
      pos 12015
      pos 12074
    doc 11
      freq 2
      pos 7995
      pos 10597
    doc 12
      freq 5
      pos 4228
      pos 4302
      pos 4314
      pos 4343
      pos 4367
    doc 13
      freq 7
      pos 153
      pos 1213
      pos 3517
      pos 4719
      pos 5516
      pos 5960
      pos 7068
    doc 14
      freq 2
      pos 1230
      pos 2499
    doc 15
      freq 9
      pos 122
      pos 350
      pos 1087
      pos 1669
      pos 1820
      pos 2498
      pos 2511
      pos 2627
      pos 3828
    doc 16
      freq 5
      pos 117
      pos 145
      pos 505
      pos 641
      pos 740
    doc 17
      freq 1
      pos 1523
    doc 18
      freq 6
      pos 540
      pos 603
      pos 755
      pos 764
      pos 1650
      pos 1935
    skipList 
      level 0
        skipDoc 9
        skipDocFP 1528333
        impacts 
          impact 
            freq 2
            norm 95
          impact 
            freq 5
            norm 100
          impact 
            freq 17
            norm 108
        impactsEnd 
        skipDoc 17
        skipDocFP 1529366
        impacts 
          impact 
            freq 1
            norm 98
          impact 
            freq 5
            norm 99
          impact 
            freq 9
            norm 104
          impact 
            freq 20
            norm 116
        impactsEnd 
  term newer
    doc 13
      freq 1
      pos 6560
  term newfangled
    doc 11
      freq 2
      pos 1491
      pos 1494
  term newfangledheader
    doc 11
      freq 1
      pos 1490
  term newman
    doc 16
      freq 1
      pos 2536
  term newmethod
    doc 11
      freq 1
      pos 6855
  term newparam
    doc 11
      freq 1
      pos 1527
  term news
    doc 7
      freq 1
      pos 1907
    doc 13
      freq 1
      pos 3108
  term newspapers
    doc 13
      freq 1
      pos 2951
  term newtrk
    doc 7
      freq 3
      pos 435
      pos 623
      pos 1657
  term newvalu
    doc 11
      freq 1
      pos 1528
  term next
    doc 0
      freq 7
      pos 2175
      pos 5223
      pos 10453
      pos 11258
      pos 11292
      pos 11323
      pos 11700
    doc 1
      freq 8
      pos 4413
      pos 6643
      pos 6767
      pos 6775
      pos 6861
      pos 6950
      pos 7556
      pos 9480
    doc 3
      freq 1
      pos 3718
    doc 4
      freq 6
      pos 316
      pos 556
      pos 1298
      pos 2853
      pos 3322
      pos 3508
    doc 5
      freq 4
      pos 1608
      pos 1620
      pos 2645
      pos 2650
    doc 6
      freq 3
      pos 1588
      pos 1867
      pos 1977
    doc 7
      freq 4
      pos 137
      pos 1426
      pos 1474
      pos 2658
    doc 12
      freq 2
      pos 8625
      pos 9038
    doc 13
      freq 1
      pos 3598
    doc 14
      freq 11
      pos 741
      pos 772
      pos 871
      pos 946
      pos 996
      pos 1062
      pos 1432
      pos 1463
      pos 1608
      pos 1648
      pos 1714
    doc 15
      freq 1
      pos 3033
    doc 18
      freq 13
      pos 193
      pos 217
      pos 237
      pos 629
      pos 641
      pos 661
      pos 690
      pos 695
      pos 783
      pos 1091
      pos 1631
      pos 1829
      pos 1854
    skipList 
      level 0
        skipDoc 12
        skipDocFP 1531675
        impacts 
          impact 
            freq 4
            norm 100
          impact 
            freq 6
            norm 108
          impact 
            freq 8
            norm 113
        impactsEnd 
  term nexthop
    doc 0
      freq 1
      pos 14735
  term nfasqrr7i1cy5a6mr12o7mqiy9ubz8w2rb9cca2thy
    doc 11
      freq 1
      pos 10150
  term nfkywvh7qas7j1zzbiup4wyq7
    doc 10
      freq 1
      pos 12614
  term nh
    doc 11
      freq 1
      pos 10089
  term niall
    doc 14
      freq 1
      pos 5350
  term nibbl
    doc 3
      freq 1
      pos 3366
    doc 12
      freq 1
      pos 778
  term nichols
    doc 1
      freq 1
      pos 9512
    doc 3
      freq 1
      pos 5877
    doc 8
      freq 1
      pos 2136
  term nick
    doc 1
      freq 1
      pos 8889
    doc 3
      freq 2
      pos 4959
      pos 4971
  term niemi
    doc 10
      freq 1
      pos 12132
  term nikander
    doc 2
      freq 1
      pos 6365
    doc 9
      freq 1
      pos 1738
  term nikolich
    doc 2
      freq 1
      pos 838
  term nils
    doc 11
      freq 1
      pos 9443
  term nimq464zgneledpqaeazwad3kofhs9
    doc 10
      freq 1
      pos 6226
  term nis
    doc 15
      freq 2
      pos 645
      pos 2244
  term nishith
    doc 6
      freq 1
      pos 3113
  term nit
    doc 10
      freq 1
      pos 12174
  term nj
    doc 11
      freq 1
      pos 10572
  term njjhfszrybtj7e8f9ijp4ns6n
    doc 11
      freq 1
      pos 10051
  term njrpmjinhukfmpewg4afipryh5
    doc 11
      freq 1
      pos 10203
  term nmgph
    doc 10
      freq 1
      pos 12567
  term nmp61yqs
    doc 11
      freq 1
      pos 10206
  term nmz
    doc 10
      freq 1
      pos 12595
  term nna
    doc 1
      freq 1
      pos 9536
    doc 3
      freq 1
      pos 5901
  term no
    doc 0
      freq 5
      pos 5566
      pos 14094
      pos 14113
      pos 16773
      pos 17337
    doc 1
      freq 12
      pos 1403
      pos 2272
      pos 2561
      pos 2614
      pos 3850
      pos 4204
      pos 4312
      pos 6510
      pos 6629
      pos 7064
      pos 7439
      pos 9718
    doc 2
      freq 6
      pos 1597
      pos 4324
      pos 4829
      pos 5999
      pos 6224
      pos 6515
    doc 3
      freq 8
      pos 2249
      pos 2803
      pos 2808
      pos 3243
      pos 5081
      pos 5097
      pos 5820
      pos 6067
    doc 4
      freq 5
      pos 2169
      pos 2583
      pos 2590
      pos 4001
      pos 6222
    doc 5
      freq 3
      pos 1611
      pos 1642
      pos 4552
    doc 6
      freq 4
      pos 1654
      pos 1937
      pos 2002
      pos 3352
    doc 7
      freq 1
      pos 3057
    doc 8
      freq 1
      pos 2274
    doc 9
      freq 4
      pos 213
      pos 216
      pos 1572
      pos 1919
    doc 10
      freq 23
      pos 249
      pos 488
      pos 603
      pos 624
      pos 3696
      pos 4327
      pos 5191
      pos 5266
      pos 5734
      pos 6812
      pos 7161
      pos 7169
      pos 7188
      pos 7559
      pos 7827
      pos 7958
      pos 8157
      pos 8196
      pos 8963
      pos 9520
      pos 10897
      pos 11094
      pos 13580
    doc 11
      freq 19
      pos 176
      pos 920
      pos 1330
      pos 1337
      pos 1507
      pos 2609
      pos 2630
      pos 4087
      pos 6330
      pos 7044
      pos 7173
      pos 7371
      pos 8263
      pos 8357
      pos 9180
      pos 9194
      pos 9214
      pos 9236
      pos 10741
    doc 12
      freq 15
      pos 722
      pos 1015
      pos 1190
      pos 2698
      pos 3121
      pos 4030
      pos 5531
      pos 5729
      pos 5758
      pos 5996
      pos 6325
      pos 6509
      pos 8159
      pos 9195
      pos 9591
    doc 13
      freq 5
      pos 740
      pos 2514
      pos 2622
      pos 4101
      pos 7206
    doc 14
      freq 6
      pos 449
      pos 497
      pos 1367
      pos 1897
      pos 2341
      pos 5672
    doc 15
      freq 7
      pos 959
      pos 1512
      pos 2120
      pos 2887
      pos 3813
      pos 4040
      pos 4191
    doc 16
      freq 10
      pos 592
      pos 600
      pos 894
      pos 986
      pos 1053
      pos 1114
      pos 1219
      pos 2454
      pos 2490
      pos 2802
    doc 17
      freq 3
      pos 1835
      pos 1981
      pos 2526
    doc 18
      freq 8
      pos 201
      pos 729
      pos 1270
      pos 1537
      pos 1550
      pos 1773
      pos 1952
      pos 2314
    skipList 
      level 0
        skipDoc 7
        skipDocFP 1534733
        impacts 
          impact 
            freq 1
            norm 100
          impact 
            freq 4
            norm 101
          impact 
            freq 8
            norm 107
          impact 
            freq 12
            norm 113
        impactsEnd 
        skipDoc 15
        skipDocFP 1535582
        impacts 
          impact 
            freq 4
            norm 95
          impact 
            freq 7
            norm 104
          impact 
            freq 15
            norm 113
          impact 
            freq 19
            norm 114
          impact 
            freq 23
            norm 116
        impactsEnd 
  term nobody
    doc 7
      freq 1
      pos 1366
  term nobodyknowsthis
    doc 11
      freq 1
      pos 9090
  term nobodyknowsthisscheme:totallyopaquecontent
    doc 11
      freq 1
      pos 7378
  term node
    doc 0
      freq 1
      pos 7597
    doc 1
      freq 1
      pos 9139
    doc 3
      freq 2
      pos 5286
      pos 5302
    doc 4
      freq 21
      pos 528
      pos 1063
      pos 1089
      pos 1163
      pos 1174
      pos 1190
      pos 1216
      pos 1795
      pos 1839
      pos 2245
      pos 2560
      pos 2729
      pos 3379
      pos 3516
      pos 3662
      pos 3680
      pos 3828
      pos 3846
      pos 4408
      pos 4424
      pos 4485
    doc 6
      freq 6
      pos 927
      pos 1263
      pos 1590
      pos 2188
      pos 2247
      pos 2289
    doc 9
      freq 37
      pos 90
      pos 94
      pos 192
      pos 255
      pos 259
      pos 399
      pos 402
      pos 411
      pos 422
      pos 427
      pos 435
      pos 557
      pos 567
      pos 678
      pos 682
      pos 845
      pos 867
      pos 878
      pos 892
      pos 1013
      pos 1017
      pos 1148
      pos 1158
      pos 1167
      pos 1173
      pos 1325
      pos 1336
      pos 1360
      pos 1448
      pos 1465
      pos 1469
      pos 1497
      pos 1503
      pos 1515
      pos 1520
      pos 1608
      pos 1611
    doc 12
      freq 26
      pos 260
      pos 1993
      pos 2044
      pos 2121
      pos 2150
      pos 2260
      pos 2553
      pos 2586
      pos 2597
      pos 2613
      pos 3230
      pos 3364
      pos 3411
      pos 3607
      pos 3666
      pos 4291
      pos 4772
      pos 4803
      pos 4873
      pos 5676
      pos 5765
      pos 5789
      pos 5944
      pos 6920
      pos 9168
      pos 9227
    doc 15
      freq 27
      pos 74
      pos 88
      pos 387
      pos 402
      pos 564
      pos 599
      pos 662
      pos 728
      pos 751
      pos 772
      pos 898
      pos 901
      pos 944
      pos 994
      pos 1032
      pos 1058
      pos 1206
      pos 1231
      pos 1241
      pos 1301
      pos 1849
      pos 1983
      pos 2177
      pos 2683
      pos 3639
      pos 3748
      pos 3984
    skipList 
      level 0
        skipDoc 15
        skipDocFP 1538279
        impacts 
          impact 
            freq 37
            norm 95
        impactsEnd 
  term node's
    doc 4
      freq 2
      pos 1122
      pos 2296
    doc 9
      freq 3
      pos 222
      pos 802
      pos 1481
    doc 12
      freq 1
      pos 1359
    doc 15
      freq 1
      pos 2006
  term nodenam
    doc 12
      freq 1
      pos 4764
  term nodes
    doc 3
      freq 1
      pos 3164
    doc 4
      freq 3
      pos 481
      pos 2327
      pos 4453
    doc 6
      freq 3
      pos 949
      pos 2260
      pos 2265
    doc 9
      freq 5
      pos 325
      pos 648
      pos 668
      pos 1225
      pos 1400
    doc 10
      freq 1
      pos 1515
    doc 12
      freq 6
      pos 2663
      pos 3770
      pos 4096
      pos 4115
      pos 4688
      pos 6544
    doc 15
      freq 11
      pos 366
      pos 437
      pos 890
      pos 1420
      pos 1597
      pos 2361
      pos 2658
      pos 3242
      pos 3331
      pos 3569
      pos 3573
  term noguc
    doc 0
      freq 1
      pos 15951
  term noise
    doc 11
      freq 1
      pos 3263
  term nokia
    doc 9
      freq 2
      pos 9
      pos 1767
    doc 13
      freq 3
      pos 18
      pos 7009
      pos 7025
  term nokia.com
    doc 9
      freq 1
      pos 1790
    doc 13
      freq 2
      pos 7021
      pos 7038
  term nom
    doc 13
      freq 1
      pos 7005
  term nominal
    doc 6
      freq 14
      pos 236
      pos 982
      pos 1199
      pos 1353
      pos 1434
      pos 1481
      pos 1546
      pos 1779
      pos 1846
      pos 1868
      pos 2191
      pos 2233
      pos 2388
      pos 2840
  term nominet
    doc 14
      freq 3
      pos 13
      pos 5509
      pos 5528
  term nominet.org.uk
    doc 14
      freq 1
      pos 5525
  term nomur
    doc 13
      freq 26
      pos 4
      pos 116
      pos 346
      pos 750
      pos 1132
      pos 1453
      pos 1812
      pos 2164
      pos 2556
      pos 2927
      pos 3294
      pos 3655
      pos 3956
      pos 4291
      pos 4666
      pos 5011
      pos 5373
      pos 5723
      pos 6002
      pos 6324
      pos 6646
      pos 6855
      pos 6936
      pos 6990
      pos 7076
      pos 7411
  term nonasc
    doc 11
      freq 2
      pos 1849
      pos 3950
  term nonce
    doc 9
      freq 4
      pos 731
      pos 742
      pos 967
      pos 979
    doc 10
      freq 1
      pos 8591
    doc 12
      freq 1
      pos 5899
  term nonces
    doc 9
      freq 2
      pos 761
      pos 1420
  term none
    doc 0
      freq 5
      pos 4605
      pos 4630
      pos 10235
      pos 10288
      pos 16685
    doc 1
      freq 1
      pos 5204
    doc 11
      freq 2
      pos 1796
      pos 4435
    doc 12
      freq 1
      pos 8526
    doc 17
      freq 1
      pos 702
  term nonetheless
    doc 12
      freq 1
      pos 4609
  term nooneknowsthisschem
    doc 11
      freq 1
      pos 8067
  term noproxiessupportthis
    doc 11
      freq 1
      pos 7757
  term nor
    doc 0
      freq 1
      pos 17386
    doc 1
      freq 4
      pos 978
      pos 2618
      pos 3859
      pos 9767
    doc 2
      freq 1
      pos 6564
    doc 3
      freq 1
      pos 6116
    doc 4
      freq 1
      pos 6271
    doc 5
      freq 1
      pos 4601
    doc 6
      freq 1
      pos 3401
    doc 7
      freq 1
      pos 3106
    doc 8
      freq 1
      pos 2323
    doc 9
      freq 1
      pos 1968
    doc 10
      freq 3
      pos 1662
      pos 10906
      pos 13629
    doc 11
      freq 2
      pos 678
      pos 10790
    doc 12
      freq 1
      pos 9640
    doc 13
      freq 1
      pos 7255
    doc 14
      freq 1
      pos 5721
    doc 15
      freq 1
      pos 4240
    doc 16
      freq 2
      pos 1121
      pos 2851
    doc 17
      freq 1
      pos 2575
    doc 18
      freq 2
      pos 1574
      pos 2363
    skipList 
      level 0
        skipDoc 7
        skipDocFP 1543290
        impacts 
          impact 
            freq 1
            norm 100
          impact 
            freq 4
            norm 113
        impactsEnd 
        skipDoc 15
        skipDocFP 1543639
        impacts 
          impact 
            freq 1
            norm 95
          impact 
            freq 2
            norm 114
          impact 
            freq 3
            norm 116
        impactsEnd 
  term nordmark
    doc 2
      freq 1
      pos 5886
    doc 4
      freq 1
      pos 5196
    doc 9
      freq 1
      pos 1748
    doc 12
      freq 2
      pos 6764
      pos 7572
  term nordoanyproxiessupportthis
    doc 11
      freq 1
      pos 7758
  term noreason
    doc 11
      freq 1
      pos 4126
  term noreason.asndj203insdf99223ndf
    doc 11
      freq 1
      pos 4142
  term norm
    doc 15
      freq 1
      pos 2429
  term normal
    doc 0
      freq 1
      pos 5801
    doc 1
      freq 1
      pos 6938
    doc 2
      freq 1
      pos 1797
    doc 10
      freq 1
      pos 3952
    doc 11
      freq 1
      pos 8422
    doc 12
      freq 1
      pos 3034
    doc 14
      freq 1
      pos 2648
  term normally
    doc 2
      freq 1
      pos 1906
    doc 5
      freq 1
      pos 422
    doc 10
      freq 5
      pos 2485
      pos 3387
      pos 3658
      pos 6710
      pos 7389
    doc 11
      freq 2
      pos 1867
      pos 3279
    doc 14
      freq 1
      pos 2511
  term normativ
    doc 0
      freq 2
      pos 173
      pos 16883
    doc 1
      freq 2
      pos 400
      pos 8892
    doc 2
      freq 1
      pos 5089
    doc 3
      freq 2
      pos 276
      pos 4307
    doc 4
      freq 3
      pos 263
      pos 5174
      pos 5872
    doc 5
      freq 2
      pos 338
      pos 4120
    doc 7
      freq 3
      pos 152
      pos 1696
      pos 1801
    doc 8
      freq 2
      pos 172
      pos 1723
    doc 9
      freq 2
      pos 143
      pos 1647
    doc 10
      freq 4
      pos 384
      pos 1783
      pos 3502
      pos 13088
    doc 11
      freq 2
      pos 567
      pos 9315
    doc 12
      freq 3
      pos 440
      pos 573
      pos 6995
    doc 13
      freq 2
      pos 336
      pos 6733
    doc 14
      freq 2
      pos 275
      pos 5360
    doc 16
      freq 1
      pos 2520
    doc 17
      freq 2
      pos 1995
      pos 2165
    doc 18
      freq 2
      pos 180
      pos 2057
    skipList 
      level 0
        skipDoc 8
        skipDocFP 1545646
        impacts 
          impact 
            freq 2
            norm 97
          impact 
            freq 3
            norm 100
        impactsEnd 
        skipDoc 17
        skipDocFP 1546079
        impacts 
          impact 
            freq 2
            norm 95
          impact 
            freq 3
            norm 113
          impact 
            freq 4
            norm 116
        impactsEnd 
  term norrman
    doc 5
      freq 2
      pos 4173
      pos 4364
  term norseth
    doc 2
      freq 2
      pos 2464
      pos 3370
  term nortel
    doc 1
      freq 1
      pos 9313
    doc 3
      freq 2
      pos 4814
      pos 4872
    doc 11
      freq 1
      pos 9615
  term nortelnetworks.com
    doc 1
      freq 1
      pos 9323
    doc 3
      freq 2
      pos 4824
      pos 4884
  term north
    doc 17
      freq 1
      pos 2374
  term northridg
    doc 6
      freq 1
      pos 3204
  term norway
    doc 7
      freq 1
      pos 2928
    doc 15
      freq 1
      pos 4042
  term not
    doc 0
      freq 184
      pos 956
      pos 960
      pos 963
      pos 965
      pos 1185
      pos 1465
      pos 1565
      pos 2231
      pos 2352
      pos 2434
      pos 2495
      pos 3011
      pos 3040
      pos 3139
      pos 3180
      pos 3357
      pos 3411
      pos 3439
      pos 3526
      pos 3594
      pos 3699
      pos 3722
      pos 3738
      pos 3776
      pos 3856
      pos 3862
      pos 3903
      pos 4008
      pos 4085
      pos 4091
      pos 4102
      pos 4211
      pos 4234
      pos 4264
      pos 4288
      pos 4356
      pos 4362
      pos 4415
      pos 4461
      pos 4482
      pos 4502
      pos 4529
      pos 4562
      pos 4655
      pos 4675
      pos 4739
      pos 4782
      pos 4889
      pos 4908
      pos 5130
      pos 5287
      pos 5413
      pos 5436
      pos 5516
      pos 5699
      pos 5883
      pos 5923
      pos 5998
      pos 6050
      pos 6116
      pos 6279
      pos 6302
      pos 6385
      pos 6554
      pos 6750
      pos 7208
      pos 7229
      pos 7290
      pos 7343
      pos 7755
      pos 7776
      pos 7847
      pos 8275
      pos 8304
      pos 8369
      pos 8397
      pos 8819
      pos 8852
      pos 8874
      pos 8917
      pos 9038
      pos 9403
      pos 9451
      pos 9476
      pos 9502
      pos 9602
      pos 9634
      pos 9659
      pos 9687
      pos 9827
      pos 9859
      pos 9885
      pos 9977
      pos 10001
      pos 10077
      pos 10134
      pos 10891
      pos 10924
      pos 11075
      pos 11108
      pos 11153
      pos 11220
      pos 11226
      pos 11251
      pos 11433
      pos 11715
      pos 11734
      pos 11756
      pos 11803
      pos 11824
      pos 12040
      pos 12073
      pos 12095
      pos 12130
      pos 12558
      pos 12908
      pos 13040
      pos 13162
      pos 13264
      pos 13481
      pos 13579
      pos 13671
      pos 13704
      pos 13773
      pos 13807
      pos 13846
      pos 13918
      pos 13997
      pos 14058
      pos 14105
      pos 14147
      pos 14187
      pos 14832
      pos 14844
      pos 14856
      pos 14868
      pos 14880
      pos 14892
      pos 14904
      pos 14916
      pos 14940
      pos 14952
      pos 14964
      pos 14976
      pos 14988
      pos 15000
      pos 15012
      pos 15024
      pos 15036
      pos 15060
      pos 15072
      pos 15084
      pos 15096
      pos 15108
      pos 15120
      pos 15132
      pos 15144
      pos 15156
      pos 15168
      pos 15192
      pos 15204
      pos 15216
      pos 15228
      pos 15240
      pos 15252
      pos 15264
      pos 15276
      pos 15288
      pos 15300
      pos 15324
      pos 15336
      pos 15348
      pos 15360
      pos 15372
      pos 15384
      pos 15396
      pos 15880
      pos 16649
      pos 16703
      pos 16753
      pos 16807
      pos 17303
      pos 17316
      pos 17383
    doc 1
      freq 89
      pos 341
      pos 901
      pos 989
      pos 1163
      pos 1167
      pos 1170
      pos 1318
      pos 1345
      pos 1535
      pos 1702
      pos 1772
      pos 1969
      pos 2383
      pos 2821
      pos 2990
      pos 3705
      pos 3787
      pos 4217
      pos 4224
      pos 4843
      pos 4898
      pos 4936
      pos 4964
      pos 5186
      pos 5324
      pos 5346
      pos 5517
      pos 5526
      pos 5541
      pos 5598
      pos 5784
      pos 5796
      pos 5823
      pos 5851
      pos 5877
      pos 5900
      pos 6198
      pos 6210
      pos 6354
      pos 6380
      pos 6403
      pos 6428
      pos 6445
      pos 6457
      pos 6475
      pos 6495
      pos 6549
      pos 6616
      pos 6623
      pos 6654
      pos 6681
      pos 6688
      pos 6738
      pos 6750
      pos 6822
      pos 6921
      pos 6943
      pos 7018
      pos 7026
      pos 7036
      pos 7053
      pos 7058
      pos 7173
      pos 7181
      pos 7188
      pos 7217
      pos 7240
      pos 7247
      pos 7278
      pos 7318
      pos 7415
      pos 8090
      pos 8137
      pos 8275
      pos 8290
      pos 8332
      pos 8369
      pos 8455
      pos 8482
      pos 8547
      pos 8557
      pos 8673
      pos 8684
      pos 8716
      pos 8777
      pos 9469
      pos 9684
      pos 9697
      pos 9764
    doc 2
      freq 25
      pos 36
      pos 600
      pos 975
      pos 1689
      pos 2048
      pos 2140
      pos 3686
      pos 3829
      pos 3977
      pos 4094
      pos 4511
      pos 4544
      pos 4570
      pos 4639
      pos 5273
      pos 5735
      pos 5915
      pos 5928
      pos 5993
      pos 6116
      pos 6126
      pos 6186
      pos 6481
      pos 6494
      pos 6561
    doc 3
      freq 40
      pos 1023
      pos 1083
      pos 1203
      pos 1238
      pos 1242
      pos 1245
      pos 1441
      pos 2079
      pos 2086
      pos 2097
      pos 2178
      pos 2440
      pos 2461
      pos 2468
      pos 2572
      pos 2746
      pos 2765
      pos 2843
      pos 2917
      pos 3183
      pos 3381
      pos 3440
      pos 3481
      pos 3493
      pos 3507
      pos 3535
      pos 3770
      pos 4161
      pos 4167
      pos 4258
      pos 5116
      pos 5137
      pos 5216
      pos 5225
      pos 5607
      pos 5805
      pos 5848
      pos 6033
      pos 6046
      pos 6113
    doc 4
      freq 31
      pos 337
      pos 447
      pos 451
      pos 454
      pos 845
      pos 921
      pos 1170
      pos 1527
      pos 1571
      pos 1608
      pos 1636
      pos 1790
      pos 1941
      pos 1955
      pos 1978
      pos 2268
      pos 2330
      pos 2550
      pos 2614
      pos 3991
      pos 4257
      pos 4309
      pos 4680
      pos 4695
      pos 4999
      pos 5034
      pos 5758
      pos 5846
      pos 6188
      pos 6201
      pos 6268
    doc 5
      freq 19
      pos 385
      pos 433
      pos 562
      pos 758
      pos 1051
      pos 1055
      pos 1058
      pos 1184
      pos 2452
      pos 3013
      pos 3087
      pos 3100
      pos 3247
      pos 3256
      pos 3609
      pos 3680
      pos 4518
      pos 4531
      pos 4598
    doc 6
      freq 10
      pos 39
      pos 66
      pos 122
      pos 2123
      pos 2141
      pos 2776
      pos 2860
      pos 3318
      pos 3331
      pos 3398
    doc 7
      freq 13
      pos 50
      pos 85
      pos 222
      pos 568
      pos 1205
      pos 1224
      pos 1447
      pos 1516
      pos 1706
      pos 1721
      pos 3023
      pos 3036
      pos 3103
    doc 8
      freq 11
      pos 284
      pos 311
      pos 315
      pos 318
      pos 373
      pos 1594
      pos 1686
      pos 1713
      pos 2240
      pos 2253
      pos 2320
    doc 9
      freq 21
      pos 329
      pos 342
      pos 348
      pos 352
      pos 355
      pos 437
      pos 510
      pos 634
      pos 657
      pos 847
      pos 971
      pos 987
      pos 1202
      pos 1304
      pos 1318
      pos 1450
      pos 1538
      pos 1552
      pos 1885
      pos 1898
      pos 1965
    doc 10
      freq 94
      pos 679
      pos 683
      pos 686
      pos 688
      pos 996
      pos 1017
      pos 1502
      pos 2256
      pos 2288
      pos 2453
      pos 2471
      pos 2489
      pos 2529
      pos 2813
      pos 3036
      pos 3083
      pos 3116
      pos 3132
      pos 3218
      pos 3245
      pos 3428
      pos 3442
      pos 3522
      pos 3594
      pos 3628
      pos 3643
      pos 3756
      pos 3761
      pos 3860
      pos 4010
      pos 4079
      pos 4097
      pos 4227
      pos 4346
      pos 4487
      pos 4582
      pos 4724
      pos 4748
      pos 5177
      pos 5242
      pos 5278
      pos 5802
      pos 5833
      pos 5853
      pos 5935
      pos 6088
      pos 6719
      pos 6803
      pos 7066
      pos 7094
      pos 7425
      pos 7666
      pos 7904
      pos 8167
      pos 8272
      pos 8495
      pos 8772
      pos 8812
      pos 8899
      pos 8979
      pos 9044
      pos 9119
      pos 9134
      pos 9184
      pos 9215
      pos 9238
      pos 9280
      pos 9426
      pos 9459
      pos 9636
      pos 9651
      pos 9767
      pos 9791
      pos 9809
      pos 9832
      pos 9931
      pos 9988
      pos 10053
      pos 10106
      pos 10133
      pos 10181
      pos 10295
      pos 10664
      pos 10858
      pos 10966
      pos 11217
      pos 11282
      pos 11430
      pos 11790
      pos 11879
      pos 12958
      pos 13546
      pos 13559
      pos 13626
    doc 11
      freq 74
      pos 52
      pos 169
      pos 566
      pos 652
      pos 667
      pos 723
      pos 848
      pos 981
      pos 1401
      pos 1620
      pos 1638
      pos 1774
      pos 1791
      pos 1814
      pos 1821
      pos 2091
      pos 2149
      pos 2168
      pos 2342
      pos 2410
      pos 2426
      pos 2452
      pos 2475
      pos 2489
      pos 2619
      pos 3306
      pos 3742
      pos 4108
      pos 4207
      pos 4401
      pos 4574
      pos 4637
      pos 4869
      pos 4987
      pos 5300
      pos 5446
      pos 5604
      pos 5770
      pos 5900
      pos 5914
      pos 6142
      pos 6407
      pos 6558
      pos 6579
      pos 6667
      pos 6819
      pos 6831
      pos 6967
      pos 7049
      pos 7187
      pos 7430
      pos 7493
      pos 7584
      pos 7808
      pos 7916
      pos 7954
      pos 7975
      pos 8004
      pos 8017
      pos 8104
      pos 8304
      pos 8402
      pos 8571
      pos 8673
      pos 8684
      pos 8697
      pos 8992
      pos 8999
      pos 9014
      pos 9382
      pos 9398
      pos 10707
      pos 10720
      pos 10787
    doc 12
      freq 93
      pos 42
      pos 568
      pos 822
      pos 829
      pos 843
      pos 938
      pos 999
      pos 1038
      pos 1174
      pos 1182
      pos 1371
      pos 1542
      pos 1550
      pos 1570
      pos 1640
      pos 1721
      pos 1849
      pos 1923
      pos 2072
      pos 2100
      pos 2129
      pos 2231
      pos 2368
      pos 2462
      pos 2504
      pos 2531
      pos 2623
      pos 2635
      pos 2673
      pos 2712
      pos 2770
      pos 3050
      pos 3290
      pos 3353
      pos 3480
      pos 3544
      pos 3562
      pos 3609
      pos 3678
      pos 3703
      pos 3728
      pos 3779
      pos 3867
      pos 3935
      pos 4091
      pos 4231
      pos 4362
      pos 4399
      pos 4490
      pos 4583
      pos 4628
      pos 4645
      pos 4661
      pos 4757
      pos 4785
      pos 4887
      pos 5177
      pos 5278
      pos 5359
      pos 5391
      pos 5464
      pos 5486
      pos 5632
      pos 5678
      pos 5915
      pos 5929
      pos 6121
      pos 6427
      pos 6471
      pos 6558
      pos 6693
      pos 6701
      pos 6848
      pos 7686
      pos 7986
      pos 7996
      pos 8025
      pos 8086
      pos 8314
      pos 8346
      pos 8451
      pos 8571
      pos 8588
      pos 8607
      pos 8610
      pos 8789
      pos 8882
      pos 9120
      pos 9125
      pos 9271
      pos 9557
      pos 9570
      pos 9637
    doc 13
      freq 23
      pos 51
      pos 1187
      pos 1191
      pos 1194
      pos 1538
      pos 1770
      pos 2299
      pos 3770
      pos 3936
      pos 4000
      pos 4538
      pos 4682
      pos 4789
      pos 4830
      pos 4954
      pos 5009
      pos 5113
      pos 5361
      pos 6278
      pos 6574
      pos 7172
      pos 7185
      pos 7252
    doc 14
      freq 9
      pos 39
      pos 390
      pos 526
      pos 1146
      pos 2294
      pos 2631
      pos 5638
      pos 5651
      pos 5718
    doc 15
      freq 33
      pos 50
      pos 754
      pos 766
      pos 803
      pos 1115
      pos 1257
      pos 1331
      pos 1509
      pos 1529
      pos 1666
      pos 1741
      pos 1842
      pos 1920
      pos 2009
      pos 2259
      pos 2660
      pos 2697
      pos 2846
      pos 3076
      pos 3194
      pos 3199
      pos 3258
      pos 3263
      pos 3296
      pos 3386
      pos 3477
      pos 3491
      pos 3577
      pos 3825
      pos 3867
      pos 4157
      pos 4170
      pos 4237
    doc 16
      freq 11
      pos 346
      pos 362
      pos 803
      pos 820
      pos 1426
      pos 1604
      pos 1611
      pos 1698
      pos 2768
      pos 2781
      pos 2848
    doc 17
      freq 14
      pos 249
      pos 271
      pos 275
      pos 278
      pos 357
      pos 401
      pos 643
      pos 766
      pos 1267
      pos 1281
      pos 1507
      pos 2492
      pos 2505
      pos 2572
    doc 18
      freq 18
      pos 386
      pos 390
      pos 393
      pos 531
      pos 612
      pos 810
      pos 828
      pos 834
      pos 852
      pos 863
      pos 1161
      pos 1243
      pos 1353
      pos 1562
      pos 1590
      pos 2280
      pos 2293
      pos 2360
    skipList 
      level 0
        skipDoc 7
        skipDocFP 1547672
        impacts 
          impact 
            freq 13
            norm 100
          impact 
            freq 19
            norm 104
          impact 
            freq 40
            norm 107
          impact 
            freq 89
            norm 113
          impact 
            freq 184
            norm 120
        impactsEnd 
        skipDoc 15
        skipDocFP 1554089
        impacts 
          impact 
            freq 21
            norm 95
          impact 
            freq 33
            norm 104
          impact 
            freq 93
            norm 113
          impact 
            freq 94
            norm 116
        impactsEnd 
  term notably
    doc 7
      freq 1
      pos 1785
    doc 10
      freq 1
      pos 473
  term notation
    doc 14
      freq 18
      pos 3207
      pos 3526
      pos 3813
      pos 4120
      pos 4183
      pos 4205
      pos 4250
      pos 4271
      pos 4375
      pos 4395
      pos 4465
      pos 4487
      pos 4548
      pos 4569
      pos 4860
      pos 4952
      pos 5123
      pos 5267
    doc 16
      freq 1
      pos 1424
    doc 17
      freq 2
      pos 477
      pos 2102
  term notational
    doc 14
      freq 3
      pos 125
      pos 568
      pos 572
  term note
    doc 0
      freq 6
      pos 2036
      pos 2071
      pos 3193
      pos 7049
      pos 10595
      pos 12764
    doc 1
      freq 9
      pos 1742
      pos 2747
      pos 2783
      pos 3431
      pos 3864
      pos 4193
      pos 5815
      pos 7283
      pos 7384
    doc 3
      freq 4
      pos 3122
      pos 5093
      pos 5102
      pos 5139
    doc 4
      freq 5
      pos 2035
      pos 3997
      pos 4987
      pos 5729
      pos 5895
    doc 5
      freq 4
      pos 746
      pos 972
      pos 1110
      pos 2267
    doc 6
      freq 1
      pos 62
    doc 8
      freq 2
      pos 278
      pos 1095
    doc 9
      freq 1
      pos 1516
    doc 10
      freq 26
      pos 1570
      pos 2627
      pos 3010
      pos 4501
      pos 4996
      pos 5236
      pos 5341
      pos 5641
      pos 5844
      pos 5881
      pos 6060
      pos 6153
      pos 6469
      pos 7061
      pos 7156
      pos 7184
      pos 7219
      pos 7868
      pos 8184
      pos 9129
      pos 9226
      pos 9451
      pos 9502
      pos 9712
      pos 9865
      pos 10581
    doc 11
      freq 6
      pos 977
      pos 1605
      pos 1617
      pos 2077
      pos 2471
      pos 4982
    doc 12
      freq 13
      pos 804
      pos 1566
      pos 2204
      pos 3196
      pos 4077
      pos 4168
      pos 4568
      pos 5387
      pos 5621
      pos 5866
      pos 6067
      pos 8041
      pos 8651
    doc 13
      freq 4
      pos 3889
      pos 4608
      pos 4934
      pos 5104
    doc 14
      freq 2
      pos 2296
      pos 2450
    doc 15
      freq 1
      pos 3721
    doc 16
      freq 5
      pos 1002
      pos 1356
      pos 1448
      pos 1908
      pos 2470
    doc 17
      freq 2
      pos 350
      pos 1679
    skipList 
      level 0
        skipDoc 9
        skipDocFP 1561636
        impacts 
          impact 
            freq 1
            norm 95
          impact 
            freq 2
            norm 97
          impact 
            freq 4
            norm 104
          impact 
            freq 5
            norm 108
          impact 
            freq 9
            norm 113
        impactsEnd 
        skipDoc 17
        skipDocFP 1562297
        impacts 
          impact 
            freq 2
            norm 98
          impact 
            freq 5
            norm 99
          impact 
            freq 13
            norm 113
          impact 
            freq 26
            norm 116
        impactsEnd 
  term noted
    doc 2
      freq 1
      pos 1558
    doc 3
      freq 2
      pos 1719
      pos 2630
    doc 6
      freq 1
      pos 1925
    doc 9
      freq 2
      pos 1082
      pos 1584
    doc 10
      freq 1
      pos 3203
    doc 12
      freq 4
      pos 6111
      pos 6903
      pos 8769
      pos 9062
    doc 15
      freq 2
      pos 838
      pos 3655
    doc 18
      freq 1
      pos 1581
    skipList 
      level 0
        skipDoc 18
        skipDocFP 1564098
        impacts 
          impact 
            freq 2
            norm 95
          impact 
            freq 4
            norm 113
        impactsEnd 
  term notes
    doc 3
      freq 2
      pos 3193
      pos 5160
    doc 6
      freq 1
      pos 113
    doc 14
      freq 2
      pos 168
      pos 1761
  term nothing
    doc 1
      freq 1
      pos 4737
    doc 7
      freq 1
      pos 1566
    doc 12
      freq 2
      pos 8282
      pos 8862
  term nothingsupportsthis
    doc 11
      freq 1
      pos 7753
  term nothingsupportsthiseither
    doc 11
      freq 1
      pos 7754
  term notic
    doc 0
      freq 1
      pos 81
    doc 1
      freq 1
      pos 98
    doc 2
      freq 1
      pos 51
    doc 3
      freq 1
      pos 92
    doc 4
      freq 1
      pos 94
    doc 5
      freq 1
      pos 78
    doc 6
      freq 1
      pos 54
    doc 7
      freq 1
      pos 65
    doc 8
      freq 1
      pos 59
    doc 9
      freq 1
      pos 80
    doc 10
      freq 1
      pos 83
    doc 11
      freq 2
      pos 67
      pos 1768
    doc 12
      freq 2
      pos 57
      pos 8285
    doc 13
      freq 1
      pos 66
    doc 14
      freq 1
      pos 61
    doc 15
      freq 1
      pos 65
    doc 16
      freq 1
      pos 79
    doc 17
      freq 11
      pos 76
      pos 925
      pos 1008
      pos 1062
      pos 1085
      pos 1092
      pos 1138
      pos 1151
      pos 1167
      pos 1237
      pos 2355
    doc 18
      freq 1
      pos 85
    skipList 
      level 0
        skipDoc 7
        skipDocFP 1565172
        impacts 
          impact 
            freq 1
            norm 100
        impactsEnd 
        skipDoc 15
        skipDocFP 1565460
        impacts 
          impact 
            freq 1
            norm 95
          impact 
            freq 2
            norm 113
        impactsEnd 
  term noticeabl
    doc 12
      freq 1
      pos 3052
  term noticed
    doc 12
      freq 2
      pos 1689
      pos 1914
  term noticeref
    doc 17
      freq 4
      pos 1103
      pos 1110
      pos 1219
      pos 1242
  term notices
    doc 0
      freq 1
      pos 1233
    doc 17
      freq 1
      pos 1158
  term notification
    doc 0
      freq 56
      pos 934
      pos 1024
      pos 1038
      pos 12278
      pos 12283
      pos 12327
      pos 12353
      pos 12406
      pos 12762
      pos 12775
      pos 12796
      pos 12827
      pos 12835
      pos 12919
      pos 12928
      pos 13000
      pos 13033
      pos 13071
      pos 13082
      pos 13099
      pos 13173
      pos 13196
      pos 13213
      pos 13275
      pos 13285
      pos 13299
      pos 13327
      pos 13375
      pos 13400
      pos 13406
      pos 13416
      pos 13430
      pos 13492
      pos 13502
      pos 13516
      pos 13590
      pos 13601
      pos 13620
      pos 13682
      pos 13691
      pos 13710
      pos 13784
      pos 13794
      pos 13857
      pos 13868
      pos 13941
      pos 13953
      pos 14069
      pos 14081
      pos 14126
      pos 14198
      pos 14209
      pos 14247
      pos 14260
      pos 15616
      pos 15621
    doc 1
      freq 14
      pos 2299
      pos 2719
      pos 4184
      pos 5170
      pos 5223
      pos 5230
      pos 5270
      pos 5322
      pos 5375
      pos 5472
      pos 5490
      pos 5580
      pos 5594
      pos 5964
    doc 3
      freq 5
      pos 1548
      pos 1563
      pos 1809
      pos 1889
      pos 5396
    doc 4
      freq 6
      pos 2727
      pos 2973
      pos 3210
      pos 3514
      pos 3701
      pos 3964
    doc 7
      freq 1
      pos 2874
    doc 13
      freq 3
      pos 4914
      pos 6028
      pos 6915
  term notifications
    doc 0
      freq 41
      pos 948
      pos 1389
      pos 3000
      pos 3009
      pos 12291
      pos 12766
      pos 12885
      pos 12897
      pos 12902
      pos 13139
      pos 13151
      pos 13156
      pos 13241
      pos 13253
      pos 13258
      pos 13458
      pos 13470
      pos 13475
      pos 13556
      pos 13568
      pos 13573
      pos 13648
      pos 13660
      pos 13665
      pos 13750
      pos 13762
      pos 13767
      pos 13823
      pos 13835
      pos 13840
      pos 13895
      pos 13907
      pos 13912
      pos 14035
      pos 14047
      pos 14052
      pos 14164
      pos 14176
      pos 14181
      pos 15623
      pos 15660
    doc 13
      freq 4
      pos 853
      pos 1780
      pos 1834
      pos 4246
  term notified
    doc 13
      freq 3
      pos 697
      pos 3576
      pos 4867
  term notifies
    doc 13
      freq 2
      pos 3541
      pos 4122
  term notify
    doc 0
      freq 15
      pos 12306
      pos 12341
      pos 12365
      pos 12390
      pos 12418
      pos 12443
      pos 12481
      pos 12507
      pos 12537
      pos 12581
      pos 12608
      pos 12656
      pos 12677
      pos 12732
      pos 12753
    doc 4
      freq 2
      pos 2737
      pos 3522
    doc 7
      freq 1
      pos 2879
    doc 13
      freq 2
      pos 1840
      pos 3036
  term noting
    doc 10
      freq 1
      pos 11368
    doc 12
      freq 1
      pos 6858
    doc 15
      freq 1
      pos 707
    doc 18
      freq 1
      pos 1753
  term notinservic
    doc 0
      freq 7
      pos 3281
      pos 3901
      pos 4413
      pos 5665
      pos 5697
      pos 10132
      pos 11431
  term nov
    doc 16
      freq 4
      pos 1968
      pos 1983
      pos 2336
      pos 2351
  term novelsc
    doc 11
      freq 1
      pos 7505
  term novelsc.asdfasser0q239nwsdfasdkl34
    doc 11
      freq 1
      pos 7525
  term november
    doc 2
      freq 3
      pos 2335
      pos 2477
      pos 6306
    doc 3
      freq 1
      pos 4694
    doc 4
      freq 1
      pos 5380
    doc 6
      freq 2
      pos 3026
      pos 3060
    doc 7
      freq 2
      pos 492
      pos 539
    doc 10
      freq 2
      pos 13149
      pos 13310
    doc 12
      freq 3
      pos 7009
      pos 7121
      pos 7724
    doc 14
      freq 2
      pos 5374
      pos 5388
    doc 16
      freq 1
      pos 2589
    skipList 
      level 0
        skipDoc 14
        skipDocFP 1570136
        impacts 
          impact 
            freq 2
            norm 100
          impact 
            freq 3
            norm 108
        impactsEnd 
  term now
    doc 1
      freq 2
      pos 6809
      pos 6914
    doc 2
      freq 3
      pos 2426
      pos 4655
      pos 4824
    doc 4
      freq 1
      pos 6011
    doc 6
      freq 1
      pos 415
    doc 7
      freq 1
      pos 108
    doc 10
      freq 3
      pos 6438
      pos 6919
      pos 7042
    doc 12
      freq 3
      pos 3648
      pos 6675
      pos 7907
    doc 14
      freq 1
      pos 1075
    doc 15
      freq 2
      pos 117
      pos 3694
    skipList 
      level 0
        skipDoc 14
        skipDocFP 1570839
        impacts 
          impact 
            freq 1
            norm 100
          impact 
            freq 3
            norm 108
        impactsEnd 
  term nr958rzxthxxzlrps1ytl4eswcja2cyv
    doc 11
      freq 1
      pos 9885
  term nrclasuhrbhbakb6chiuhoyxwe8sbkk1ctfvtwbspddagwjz1vatervawpwnbfih
    doc 10
      freq 1
      pos 12764
  term nrxvtservix7olasc05cwdpgxcnwtw2ntesxygjncuc
    doc 11
      freq 1
      pos 10379
  term ns
    doc 12
      freq 3
      pos 2851
      pos 8411
      pos 8415
    doc 18
      freq 1
      pos 1137
  term ns.child.example.com
    doc 12
      freq 6
      pos 2852
      pos 2853
      pos 2858
      pos 8416
      pos 8417
      pos 8421
  term nsaibeuybgauaymcqj9lyeyiochbehiq6byxo1i1tm2csbchqowc7aakkxqq
    doc 11
      freq 1
      pos 9901
  term nsap
    doc 0
      freq 8
      pos 1420
      pos 9954
      pos 10015
      pos 10333
      pos 10442
      pos 10667
      pos 10675
      pos 15730
  term nsaps
    doc 0
      freq 1
      pos 9988
  term nsec
    doc 14
      freq 17
      pos 93
      pos 301
      pos 320
      pos 1782
      pos 1807
      pos 1815
      pos 1826
      pos 1854
      pos 2133
      pos 2330
      pos 2400
      pos 2432
      pos 2576
      pos 2600
      pos 2715
      pos 2773
      pos 5476
    doc 18
      freq 57
      pos 25
      pos 100
      pos 143
      pos 164
      pos 189
      pos 224
      pos 247
      pos 256
      pos 293
      pos 309
      pos 572
      pos 579
      pos 604
      pos 623
      pos 635
      pos 715
      pos 742
      pos 756
      pos 765
      pos 796
      pos 805
      pos 826
      pos 860
      pos 876
      pos 915
      pos 932
      pos 988
      pos 1011
      pos 1015
      pos 1019
      pos 1022
      pos 1031
      pos 1058
      pos 1087
      pos 1103
      pos 1109
      pos 1134
      pos 1140
      pos 1150
      pos 1272
      pos 1373
      pos 1386
      pos 1454
      pos 1457
      pos 1524
      pos 1527
      pos 1533
      pos 1616
      pos 1627
      pos 1790
      pos 1813
      pos 1913
      pos 1931
      pos 1946
      pos 1980
      pos 2153
      pos 2196
  term nsec's
    doc 18
      freq 2
      pos 209
      pos 655
  term nsec3
    doc 18
      freq 1
      pos 538
  term nsllzowi58uvu7
    doc 10
      freq 1
      pos 6865
  term nslookup
    doc 14
      freq 1
      pos 2123
  term nsp
    doc 1
      freq 1
      pos 2039
    doc 3
      freq 16
      pos 879
      pos 896
      pos 970
      pos 1066
      pos 1358
      pos 1398
      pos 1488
      pos 1533
      pos 2130
      pos 2312
      pos 2322
      pos 2525
      pos 2656
      pos 3131
      pos 5121
      pos 5149
  term nsps
    doc 3
      freq 2
      pos 1155
      pos 1207
  term nt9bobg
    doc 10
      freq 1
      pos 12742
  term nth
    doc 0
      freq 1
      pos 12151
  term ntp
    doc 5
      freq 3
      pos 1991
      pos 2205
      pos 2501
    doc 15
      freq 10
      pos 419
      pos 625
      pos 679
      pos 1250
      pos 1269
      pos 1552
      pos 1601
      pos 1624
      pos 1927
      pos 2154
  term nu2qjd
    doc 11
      freq 1
      pos 10481
  term nul
    doc 11
      freq 1
      pos 1947
  term null
    doc 0
      freq 2
      pos 10292
      pos 10778
    doc 1
      freq 3
      pos 3505
      pos 3536
      pos 3770
    doc 3
      freq 2
      pos 5170
      pos 5260
    doc 6
      freq 1
      pos 2125
    doc 11
      freq 5
      pos 1681
      pos 2364
      pos 2369
      pos 3713
      pos 9231
    doc 14
      freq 1
      pos 2383
    doc 18
      freq 2
      pos 1288
      pos 1322
  term nulls
    doc 11
      freq 3
      pos 159
      pos 2300
      pos 2310
  term number
    doc 0
      freq 67
      pos 676
      pos 1543
      pos 2300
      pos 2477
      pos 2674
      pos 3073
      pos 3378
      pos 3623
      pos 4139
      pos 7173
      pos 7309
      pos 7322
      pos 7381
      pos 7396
      pos 7414
      pos 7429
      pos 7453
      pos 7480
      pos 7522
      pos 7534
      pos 7553
      pos 7558
      pos 7580
      pos 7610
      pos 7624
      pos 7691
      pos 7708
      pos 7724
      pos 7908
      pos 7939
      pos 7976
      pos 8017
      pos 8040
      pos 8056
      pos 8097
      pos 8151
      pos 8188
      pos 8222
      pos 8254
      pos 8429
      pos 8450
      pos 8498
      pos 8518
      pos 8556
      pos 8576
      pos 8613
      pos 8646
      pos 8670
      pos 8691
      pos 8715
      pos 8736
      pos 8760
      pos 8778
      pos 10980
      pos 11855
      pos 12006
      pos 12186
      pos 12809
      pos 12864
      pos 12946
      pos 13011
      pos 13371
      pos 13383
      pos 14350
      pos 14404
      pos 14570
      pos 16094
    doc 1
      freq 10
      pos 1290
      pos 7374
      pos 7463
      pos 7494
      pos 7508
      pos 7563
      pos 7573
      pos 7596
      pos 7661
      pos 7686
    doc 2
      freq 2
      pos 384
      pos 4168
    doc 3
      freq 7
      pos 3673
      pos 3724
      pos 3739
      pos 3745
      pos 3756
      pos 3766
      pos 3774
    doc 4
      freq 10
      pos 303
      pos 3587
      pos 3635
      pos 3638
      pos 3758
      pos 3807
      pos 3810
      pos 4396
      pos 4450
      pos 4562
    doc 5
      freq 6
      pos 1084
      pos 1410
      pos 1654
      pos 1665
      pos 1966
      pos 2757
    doc 6
      freq 5
      pos 373
      pos 1270
      pos 1276
      pos 1423
      pos 2846
    doc 7
      freq 2
      pos 1902
      pos 2849
    doc 8
      freq 2
      pos 1022
      pos 1311
    doc 9
      freq 5
      pos 836
      pos 910
      pos 1278
      pos 1424
      pos 1456
    doc 10
      freq 9
      pos 515
      pos 1685
      pos 4507
      pos 7742
      pos 11292
      pos 11628
      pos 11723
      pos 11824
      pos 11918
    doc 11
      freq 3
      pos 4761
      pos 4969
      pos 6655
    doc 12
      freq 3
      pos 1339
      pos 1436
      pos 3669
    doc 13
      freq 5
      pos 1661
      pos 1736
      pos 3332
      pos 3722
      pos 4884
    doc 14
      freq 3
      pos 2360
      pos 3222
      pos 3828
    doc 15
      freq 3
      pos 2526
      pos 2648
      pos 3230
    doc 17
      freq 3
      pos 1120
      pos 1139
      pos 1744
    doc 18
      freq 4
      pos 557
      pos 1181
      pos 1195
      pos 1568
    skipList 
      level 0
        skipDoc 7
        skipDocFP 1575110
        impacts 
          impact 
            freq 2
            norm 100
          impact 
            freq 5
            norm 101
          impact 
            freq 6
            norm 104
          impact 
            freq 7
            norm 107
          impact 
            freq 10
            norm 108
          impact 
            freq 67
            norm 120
        impactsEnd 
        skipDoc 15
        skipDocFP 1576942
        impacts 
          impact 
            freq 5
            norm 95
          impact 
            freq 9
            norm 116
        impactsEnd 
  term numbered
    doc 10
      freq 1
      pos 8649
  term numbers
    doc 0
      freq 1
      pos 15827
    doc 2
      freq 1
      pos 5579
    doc 5
      freq 1
      pos 116
    doc 6
      freq 3
      pos 839
      pos 861
      pos 2529
    doc 7
      freq 2
      pos 477
      pos 1617
    doc 9
      freq 2
      pos 1296
      pos 1316
    doc 10
      freq 5
      pos 7409
      pos 7436
      pos 7637
      pos 7758
      pos 13320
    doc 13
      freq 4
      pos 2527
      pos 3985
      pos 4010
      pos 6392
    doc 14
      freq 1
      pos 2940
    doc 15
      freq 1
      pos 1559
    skipList 
      level 0
        skipDoc 13
        skipDocFP 1578507
        impacts 
          impact 
            freq 2
            norm 95
          impact 
            freq 3
            norm 101
          impact 
            freq 4
            norm 109
          impact 
            freq 5
            norm 116
        impactsEnd 
  term numeric
    doc 8
      freq 1
      pos 353
    doc 11
      freq 1
      pos 4593
    doc 18
      freq 1
      pos 1352
  term numerically
    doc 18
      freq 1
      pos 1341
  term numerous
    doc 12
      freq 1
      pos 6545
    doc 13
      freq 1
      pos 973
  term nvgtv1du6x7
    doc 10
      freq 1
      pos 12639
  term nvxdulbrrp35flmvfycxdz9mrhgr
    doc 10
      freq 1
      pos 12584
  term nw
    doc 11
      freq 1
      pos 10543
  term nx15k4aam6p
    doc 10
      freq 1
      pos 12564
  term nxoloiv9ogjb
    doc 10
      freq 1
      pos 12461
  term ny
    doc 11
      freq 1
      pos 10599
    doc 13
      freq 1
      pos 7070
  term ny9x52jqodsf34cq
    doc 11
      freq 1
      pos 10161
  term nycrmgwkdao6gz
    doc 10
      freq 1
      pos 12784
  term nyicrjel9kjssmwe4ae2dowifkowlbc8mjo9fcgffnlymdr6toqrohdhkccf
    doc 11
      freq 1
      pos 10041
  term nzncqf78riy2lk6qq6dnfo30q4b2jalg2wtkcz2uvx7
    doc 10
      freq 1
      pos 12503
  term nzzel
    doc 10
      freq 1
      pos 6842
  term o'reilly
    doc 14
      freq 1
      pos 5351
  term o.example.com
    doc 14
      freq 2
      pos 4246
      pos 4267
  term o.ooooooooooooooooooooooooooooooooooooooooooooo
    doc 14
      freq 1
      pos 4242
  term o2004
    doc 12
      freq 2
      pos 4064
      pos 7759
  term o2zyewnoiztfjl5r
    doc 11
      freq 1
      pos 10339
  term o3yn8t3p0usm1gyg9lqgeibxfe6
    doc 10
      freq 1
      pos 12478
  term o67pbhzr
    doc 10
      freq 1
      pos 12492
  term o7ztz1ke8wtnxhfuclu5gglz6l
    doc 10
      freq 1
      pos 12477
  term o9ym9mxtfwqpi3axrv2ak
    doc 11
      freq 1
      pos 10497
  term oa0mpeqt7rtktrdx1cztzgezbm7rllvqebnhwzwov5qdzedmahlzto8wq0ozol4x
    doc 10
      freq 1
      pos 12483
  term oam
    doc 3
      freq 2
      pos 3310
      pos 3458
  term obbylrmpjskraqwoigpauxi3
    doc 10
      freq 1
      pos 6833
  term object
    doc 0
      freq 363
      pos 1022
      pos 1036
      pos 1257
      pos 1262
      pos 1267
      pos 1271
      pos 1278
      pos 1292
      pos 1302
      pos 1317
      pos 1326
      pos 1338
      pos 1349
      pos 1366
      pos 1382
      pos 1391
      pos 2132
      pos 2171
      pos 2220
      pos 2261
      pos 2278
      pos 2283
      pos 2318
      pos 2350
      pos 2383
      pos 2423
      pos 2463
      pos 2493
      pos 2526
      pos 2565
      pos 2607
      pos 2659
      pos 2688
      pos 2709
      pos 2741
      pos 2768
      pos 2802
      pos 2850
      pos 2941
      pos 2973
      pos 2986
      pos 3032
      pos 3094
      pos 3133
      pos 3174
      pos 3230
      pos 3275
      pos 3309
      pos 3349
      pos 3405
      pos 3465
      pos 3518
      pos 3588
      pos 3693
      pos 3716
      pos 3766
      pos 3770
      pos 3848
      pos 3879
      pos 3916
      pos 3922
      pos 3952
      pos 4000
      pos 4096
      pos 4193
      pos 4228
      pos 4260
      pos 4282
      pos 4348
      pos 4379
      pos 4428
      pos 4453
      pos 4476
      pos 4523
      pos 4556
      pos 4582
      pos 4609
      pos 4647
      pos 4669
      pos 4733
      pos 4753
      pos 4780
      pos 4806
      pos 4862
      pos 4937
      pos 4961
      pos 5012
      pos 5018
      pos 5051
      pos 5110
      pos 5138
      pos 5167
      pos 5197
      pos 5226
      pos 5250
      pos 5278
      pos 5307
      pos 5354
      pos 5405
      pos 5430
      pos 5510
      pos 5538
      pos 5577
      pos 5613
      pos 5622
      pos 5644
      pos 5712
      pos 5718
      pos 5745
      pos 5787
      pos 5824
      pos 5891
      pos 5901
      pos 5934
      pos 6017
      pos 6077
      pos 6131
      pos 6187
      pos 6211
      pos 6271
      pos 6296
      pos 6379
      pos 6399
      pos 6440
      pos 6466
      pos 6498
      pos 6608
      pos 6638
      pos 6718
      pos 6777
      pos 6834
      pos 6914
      pos 6928
      pos 6961
      pos 6975
      pos 7015
      pos 7044
      pos 7093
      pos 7136
      pos 7150
      pos 7179
      pos 7200
      pos 7223
      pos 7284
      pos 7304
      pos 7376
      pos 7409
      pos 7442
      pos 7469
      pos 7499
      pos 7542
      pos 7569
      pos 7605
      pos 7652
      pos 7668
      pos 7703
      pos 7747
      pos 7770
      pos 7835
      pos 7896
      pos 7927
      pos 7964
      pos 8005
      pos 8035
      pos 8085
      pos 8127
      pos 8176
      pos 8210
      pos 8267
      pos 8298
      pos 8363
      pos 8387
      pos 8412
      pos 8493
      pos 8551
      pos 8608
      pos 8665
      pos 8710
      pos 8755
      pos 8811
      pos 8846
      pos 8909
      pos 8965
      pos 8996
      pos 9049
      pos 9086
      pos 9118
      pos 9144
      pos 9174
      pos 9232
      pos 9288
      pos 9318
      pos 9395
      pos 9445
      pos 9494
      pos 9528
      pos 9582
      pos 9628
      pos 9679
      pos 9710
      pos 9751
      pos 9787
      pos 9819
      pos 9853
      pos 9913
      pos 9969
      pos 9995
      pos 10069
      pos 10104
      pos 10123
      pos 10147
      pos 10153
      pos 10184
      pos 10194
      pos 10217
      pos 10231
      pos 10275
      pos 10316
      pos 10427
      pos 10448
      pos 10466
      pos 10489
      pos 10503
      pos 10523
      pos 10537
      pos 10574
      pos 10613
      pos 10656
      pos 10672
      pos 10696
      pos 10711
      pos 10780
      pos 10795
      pos 10883
      pos 10918
      pos 11069
      pos 11102
      pos 11143
      pos 11147
      pos 11212
      pos 11243
      pos 11276
      pos 11310
      pos 11341
      pos 11345
      pos 11393
      pos 11401
      pos 11420
      pos 11446
      pos 11452
      pos 11472
      pos 11496
      pos 11519
      pos 11529
      pos 11549
      pos 11559
      pos 11583
      pos 11593
      pos 11627
      pos 11649
      pos 11707
      pos 11728
      pos 11797
      pos 11818
      pos 11842
      pos 11862
      pos 11896
      pos 11918
      pos 11942
      pos 11961
      pos 12032
      pos 12067
      pos 12122
      pos 12161
      pos 12193
      pos 12215
      pos 12234
      pos 12253
      pos 12293
      pos 12298
      pos 12331
      pos 12357
      pos 12382
      pos 12410
      pos 12435
      pos 12473
      pos 12497
      pos 12527
      pos 12571
      pos 12596
      pos 12628
      pos 12669
      pos 12722
      pos 12745
      pos 12854
      pos 14373
      pos 14378
      pos 14416
      pos 14440
      pos 14446
      pos 14470
      pos 14506
      pos 14582
      pos 14606
      pos 14612
      pos 14636
      pos 14672
      pos 14696
      pos 14720
      pos 14822
      pos 14834
      pos 14846
      pos 14858
      pos 14870
      pos 14882
      pos 14894
      pos 14906
      pos 14930
      pos 14942
      pos 14954
      pos 14966
      pos 14978
      pos 14990
      pos 15002
      pos 15014
      pos 15026
      pos 15038
      pos 15062
      pos 15074
      pos 15086
      pos 15098
      pos 15110
      pos 15122
      pos 15134
      pos 15146
      pos 15158
      pos 15170
      pos 15194
      pos 15206
      pos 15218
      pos 15230
      pos 15242
      pos 15254
      pos 15266
      pos 15278
      pos 15290
      pos 15314
      pos 15326
      pos 15338
      pos 15350
      pos 15362
      pos 15374
      pos 15386
      pos 15403
      pos 15476
      pos 15544
      pos 15590
      pos 15668
      pos 15693
      pos 15735
      pos 15764
      pos 15820
      pos 15830
    doc 7
      freq 2
      pos 1112
      pos 2771
    doc 17
      freq 17
      pos 524
      pos 580
      pos 806
      pos 837
      pos 845
      pos 853
      pos 861
      pos 886
      pos 909
      pos 948
      pos 1953
      pos 2264
      pos 2272
      pos 2280
      pos 2289
      pos 2327
      pos 2339
  term objectdigestinf
    doc 17
      freq 1
      pos 1800
  term objects
    doc 0
      freq 59
      pos 223
      pos 239
      pos 250
      pos 343
      pos 354
      pos 373
      pos 430
      pos 458
      pos 1386
      pos 2111
      pos 2228
      pos 2254
      pos 2265
      pos 3796
      pos 4308
      pos 11172
      pos 12777
      pos 12829
      pos 12921
      pos 13002
      pos 13073
      pos 13175
      pos 13277
      pos 13329
      pos 13408
      pos 13494
      pos 13592
      pos 13684
      pos 13786
      pos 13859
      pos 13943
      pos 14071
      pos 14200
      pos 14249
      pos 14366
      pos 14407
      pos 14434
      pos 14573
      pos 14600
      pos 15405
      pos 15465
      pos 15478
      pos 15533
      pos 15546
      pos 15579
      pos 15592
      pos 15612
      pos 15670
      pos 15684
      pos 15695
      pos 15712
      pos 15737
      pos 15754
      pos 15766
      pos 15784
      pos 16097
      pos 16116
      pos 16794
      pos 16863
    doc 2
      freq 9
      pos 2909
      pos 2930
      pos 3000
      pos 3216
      pos 3233
      pos 3252
      pos 3378
      pos 3394
      pos 3826
    doc 7
      freq 13
      pos 879
      pos 988
      pos 1025
      pos 1058
      pos 2010
      pos 2289
      pos 2307
      pos 2324
      pos 2343
      pos 2476
      pos 2570
      pos 2635
      pos 2694
  term observ
    doc 0
      freq 2
      pos 15787
      pos 16436
    doc 4
      freq 1
      pos 1349
  term observations
    doc 7
      freq 2
      pos 131
      pos 465
    doc 15
      freq 1
      pos 3598
  term observed
    doc 6
      freq 2
      pos 1171
      pos 1316
    doc 12
      freq 6
      pos 211
      pos 649
      pos 1616
      pos 1633
      pos 4780
      pos 7749
    doc 17
      freq 1
      pos 1336
  term observing
    doc 0
      freq 1
      pos 16531
  term obsolet
    doc 7
      freq 3
      pos 33
      pos 328
      pos 1192
  term obsoletes
    doc 4
      freq 2
      pos 10
      pos 431
  term obtain
    doc 0
      freq 1
      pos 17448
    doc 1
      freq 1
      pos 9829
    doc 2
      freq 5
      pos 853
      pos 1966
      pos 4293
      pos 5348
      pos 6626
    doc 3
      freq 1
      pos 6178
    doc 4
      freq 2
      pos 873
      pos 6333
    doc 5
      freq 1
      pos 4663
    doc 6
      freq 2
      pos 1357
      pos 3463
    doc 7
      freq 1
      pos 3168
    doc 8
      freq 1
      pos 2385
    doc 9
      freq 1
      pos 2030
    doc 10
      freq 1
      pos 13691
    doc 11
      freq 1
      pos 10852
    doc 12
      freq 2
      pos 8847
      pos 9702
    doc 13
      freq 1
      pos 7317
    doc 14
      freq 1
      pos 5783
    doc 15
      freq 5
      pos 92
      pos 607
      pos 1035
      pos 1083
      pos 4302
    doc 16
      freq 1
      pos 2913
    doc 17
      freq 1
      pos 2637
    doc 18
      freq 1
      pos 2425
    skipList 
      level 0
        skipDoc 7
        skipDocFP 1589336
        impacts 
          impact 
            freq 1
            norm 100
          impact 
            freq 2
            norm 101
          impact 
            freq 5
            norm 108
        impactsEnd 
        skipDoc 15
        skipDocFP 1589729
        impacts 
          impact 
            freq 1
            norm 95
          impact 
            freq 5
            norm 104
        impactsEnd 
  term obtained
    doc 0
      freq 2
      pos 16203
      pos 17470
    doc 1
      freq 1
      pos 9851
    doc 2
      freq 3
      pos 586
      pos 2001
      pos 6648
    doc 3
      freq 1
      pos 6200
    doc 4
      freq 1
      pos 6355
    doc 5
      freq 1
      pos 4685
    doc 6
      freq 3
      pos 1117
      pos 2509
      pos 3485
    doc 7
      freq 1
      pos 3190
    doc 8
      freq 1
      pos 2407
    doc 9
      freq 1
      pos 2052
    doc 10
      freq 3
      pos 2655
      pos 8322
      pos 13713
    doc 11
      freq 1
      pos 10874
    doc 12
      freq 5
      pos 979
      pos 3056
      pos 4730
      pos 6607
      pos 9724
    doc 13
      freq 1
      pos 7339
    doc 14
      freq 1
      pos 5805
    doc 15
      freq 1
      pos 4324
    doc 16
      freq 1
      pos 2935
    doc 17
      freq 1
      pos 2659
    doc 18
      freq 1
      pos 2447
    skipList 
      level 0
        skipDoc 7
        skipDocFP 1590726
        impacts 
          impact 
            freq 1
            norm 100
          impact 
            freq 3
            norm 101
        impactsEnd 
        skipDoc 15
        skipDocFP 1591106
        impacts 
          impact 
            freq 1
            norm 95
          impact 
            freq 5
            norm 113
        impactsEnd 
  term obtaining
    doc 2
      freq 1
      pos 2034
    doc 12
      freq 3
      pos 336
      pos 3960
      pos 4016
    doc 15
      freq 1
      pos 451
  term obvious
    doc 10
      freq 1
      pos 5676
    doc 12
      freq 1
      pos 989
    doc 14
      freq 1
      pos 408
    doc 16
      freq 1
      pos 304
    doc 18
      freq 1
      pos 1904
  term obviously
    doc 1
      freq 1
      pos 8540
    doc 10
      freq 1
      pos 1630
    doc 12
      freq 3
      pos 2253
      pos 3198
      pos 4114
    doc 18
      freq 1
      pos 1825
  term occasionally
    doc 10
      freq 1
      pos 4927
  term occur
    doc 2
      freq 2
      pos 641
      pos 1165
    doc 4
      freq 4
      pos 1853
      pos 2324
      pos 2391
      pos 2658
    doc 7
      freq 1
      pos 1448
    doc 12
      freq 4
      pos 1807
      pos 2232
      pos 5534
      pos 5560
    doc 14
      freq 7
      pos 343
      pos 371
      pos 1088
      pos 1726
      pos 2295
      pos 2311
      pos 2317
    doc 15
      freq 1
      pos 2167
    doc 17
      freq 3
      pos 1605
      pos 1818
      pos 1840
  term occurred
    doc 0
      freq 2
      pos 7561
      pos 7916
    doc 2
      freq 1
      pos 1109
    doc 10
      freq 1
      pos 3717
  term occurrenc
    doc 1
      freq 1
      pos 3883
  term occurrences
    doc 1
      freq 2
      pos 3913
      pos 3923
  term occurring
    doc 2
      freq 1
      pos 5410
  term occurs
    doc 10
      freq 1
      pos 5682
    doc 11
      freq 1
      pos 2179
  term oct
    doc 11
      freq 1
      pos 3842
  term octet
    doc 0
      freq 14
      pos 1427
      pos 1492
      pos 1577
      pos 1965
      pos 1988
      pos 3220
      pos 6709
      pos 6768
      pos 10652
      pos 10663
      pos 12119
      pos 12256
      pos 12370
      pos 12599
    doc 1
      freq 3
      pos 3757
      pos 5114
      pos 6142
    doc 2
      freq 1
      pos 1654
    doc 3
      freq 1
      pos 474
    doc 4
      freq 2
      pos 3334
      pos 3459
    doc 11
      freq 2
      pos 1028
      pos 3870
    doc 14
      freq 34
      pos 757
      pos 781
      pos 800
      pos 816
      pos 934
      pos 953
      pos 981
      pos 1008
      pos 1448
      pos 1486
      pos 1505
      pos 1516
      pos 1633
      pos 1660
      pos 1965
      pos 1967
      pos 1973
      pos 1981
      pos 1987
      pos 1989
      pos 1996
      pos 2003
      pos 2249
      pos 2272
      pos 2916
      pos 2932
      pos 3227
      pos 3242
      pos 3272
      pos 3556
      pos 3833
      pos 4166
      pos 4524
      pos 4993
    doc 18
      freq 3
      pos 1291
      pos 1325
      pos 1328
    skipList 
      level 0
        skipDoc 18
        skipDocFP 1593663
        impacts 
          impact 
            freq 3
            norm 97
          impact 
            freq 34
            norm 107
        impactsEnd 
  term octets
    doc 0
      freq 3
      pos 3626
      pos 4142
      pos 10983
    doc 1
      freq 5
      pos 2595
      pos 3829
      pos 5137
      pos 6148
      pos 6268
    doc 4
      freq 1
      pos 3656
    doc 8
      freq 1
      pos 1017
    doc 9
      freq 1
      pos 728
    doc 11
      freq 7
      pos 207
      pos 3205
      pos 3231
      pos 3244
      pos 3304
      pos 8363
      pos 9225
    doc 14
      freq 19
      pos 681
      pos 722
      pos 860
      pos 888
      pos 918
      pos 972
      pos 1040
      pos 1049
      pos 1535
      pos 1624
      pos 1692
      pos 1701
      pos 1742
      pos 1946
      pos 2057
      pos 2221
      pos 2362
      pos 2373
      pos 4434
    doc 16
      freq 3
      pos 752
      pos 768
      pos 1099
    doc 18
      freq 2
      pos 1313
      pos 1315
    skipList 
      level 0
        skipDoc 16
        skipDocFP 1594990
        impacts 
          impact 
            freq 1
            norm 95
          impact 
            freq 3
            norm 99
          impact 
            freq 19
            norm 107
        impactsEnd 
  term october
    doc 0
      freq 1
      pos 17145
    doc 2
      freq 2
      pos 2816
      pos 2844
    doc 4
      freq 1
      pos 5264
    doc 5
      freq 1
      pos 4160
    doc 7
      freq 1
      pos 1816
    doc 8
      freq 1
      pos 1744
    doc 10
      freq 1
      pos 13198
    doc 12
      freq 6
      pos 7278
      pos 7421
      pos 7587
      pos 7605
      pos 7674
      pos 7696
    doc 13
      freq 1
      pos 6784
    doc 16
      freq 1
      pos 2619
    skipList 
      level 0
        skipDoc 12
        skipDocFP 1596121
        impacts 
          impact 
            freq 1
            norm 97
          impact 
            freq 2
            norm 108
          impact 
            freq 6
            norm 113
        impactsEnd 
  term od7yqzx9ezqbtflk4gznxzurp
    doc 10
      freq 1
      pos 12811
  term od9iblypiydjudxr4en9xuhqdhmidgp6vsjyybvte85dwijmty65t2pdtkjqa4gz
    doc 10
      freq 1
      pos 12538
  term of
    doc 0
      freq 427
      pos 29
      pos 57
      pos 71
      pos 75
      pos 94
      pos 139
      pos 156
      pos 202
      pos 218
      pos 263
      pos 352
      pos 380
      pos 418
      pos 472
      pos 539
      pos 603
      pos 652
      pos 677
      pos 687
      pos 694
      pos 707
      pos 715
      pos 766
      pos 769
      pos 784
      pos 787
      pos 803
      pos 902
      pos 922
      pos 1002
      pos 1108
      pos 1180
      pos 1217
      pos 1223
      pos 1253
      pos 1372
      pos 1511
      pos 1516
      pos 1534
      pos 1573
      pos 1640
      pos 1662
      pos 1689
      pos 1724
      pos 1738
      pos 1789
      pos 1821
      pos 1843
      pos 1872
      pos 1898
      pos 1938
      pos 1984
      pos 2013
      pos 2121
      pos 2129
      pos 2168
      pos 2177
      pos 2189
      pos 2217
      pos 2240
      pos 2301
      pos 2406
      pos 2418
      pos 2478
      pos 2675
      pos 2735
      pos 2823
      pos 2866
      pos 2963
      pos 2997
      pos 3036
      pos 3047
      pos 3064
      pos 3074
      pos 3110
      pos 3118
      pos 3218
      pos 3224
      pos 3255
      pos 3307
      pos 3329
      pos 3332
      pos 3353
      pos 3364
      pos 3367
      pos 3498
      pos 3522
      pos 3533
      pos 3570
      pos 3624
      pos 3639
      pos 3706
      pos 3755
      pos 3763
      pos 3783
      pos 3818
      pos 3835
      pos 3840
      pos 3893
      pos 3914
      pos 4004
      pos 4140
      pos 4155
      pos 4218
      pos 4249
      pos 4257
      pos 4295
      pos 4318
      pos 4335
      pos 4340
      pos 4393
      pos 4426
      pos 4438
      pos 4457
      pos 4468
      pos 4537
      pos 4651
      pos 4767
      pos 4840
      pos 4875
      pos 4993
      pos 4996
      pos 5006
      pos 5099
      pos 5133
      pos 5151
      pos 5180
      pos 5274
      pos 5293
      pos 5305
      pos 5323
      pos 5352
      pos 5409
      pos 5420
      pos 5551
      pos 5561
      pos 5602
      pos 5636
      pos 5658
      pos 5671
      pos 5710
      pos 5741
      pos 5759
      pos 5778
      pos 5803
      pos 5806
      pos 5838
      pos 5864
      pos 5968
      pos 6152
      pos 6159
      pos 6275
      pos 6413
      pos 6455
      pos 6551
      pos 6636
      pos 6674
      pos 6731
      pos 6819
      pos 6899
      pos 6992
      pos 6998
      pos 7037
      pos 7109
      pos 7116
      pos 7120
      pos 7195
      pos 7204
      pos 7310
      pos 7323
      pos 7382
      pos 7397
      pos 7415
      pos 7430
      pos 7454
      pos 7481
      pos 7523
      pos 7554
      pos 7581
      pos 7587
      pos 7611
      pos 7625
      pos 7641
      pos 7692
      pos 7709
      pos 7725
      pos 7737
      pos 7751
      pos 7854
      pos 7909
      pos 7940
      pos 7977
      pos 7980
      pos 8018
      pos 8041
      pos 8057
      pos 8098
      pos 8152
      pos 8189
      pos 8223
      pos 8252
      pos 8255
      pos 8271
      pos 8430
      pos 8451
      pos 8499
      pos 8519
      pos 8557
      pos 8577
      pos 8614
      pos 8647
      pos 8671
      pos 8692
      pos 8716
      pos 8737
      pos 8761
      pos 8779
      pos 8815
      pos 8838
      pos 8986
      pos 9018
      pos 9032
      pos 9063
      pos 9107
      pos 9132
      pos 9300
      pos 9341
      pos 9349
      pos 9382
      pos 9385
      pos 9399
      pos 9413
      pos 9416
      pos 9568
      pos 9571
      pos 9586
      pos 9612
      pos 9615
      pos 9723
      pos 9776
      pos 9784
      pos 9805
      pos 9823
      pos 9837
      pos 9973
      pos 9984
      pos 10118
      pos 10145
      pos 10179
      pos 10207
      pos 10252
      pos 10283
      pos 10301
      pos 10330
      pos 10351
      pos 10397
      pos 10405
      pos 10424
      pos 10435
      pos 10569
      pos 10653
      pos 10665
      pos 10678
      pos 10683
      pos 10824
      pos 10828
      pos 10838
      pos 10845
      pos 10887
      pos 10898
      pos 10981
      pos 10997
      pos 11082
      pos 11115
      pos 11132
      pos 11140
      pos 11160
      pos 11182
      pos 11199
      pos 11204
      pos 11257
      pos 11289
      pos 11330
      pos 11338
      pos 11362
      pos 11368
      pos 11378
      pos 11385
      pos 11414
      pos 11444
      pos 11466
      pos 11682
      pos 11711
      pos 11722
      pos 11955
      pos 11987
      pos 12028
      pos 12036
      pos 12059
      pos 12137
      pos 12156
      pos 12228
      pos 12247
      pos 12270
      pos 12347
      pos 12400
      pos 12514
      pos 12544
      pos 12588
      pos 12614
      pos 12663
      pos 12701
      pos 12810
      pos 12821
      pos 12840
      pos 12865
      pos 12882
      pos 12898
      pos 12947
      pos 12967
      pos 13057
      pos 13115
      pos 13127
      pos 13136
      pos 13152
      pos 13217
      pos 13229
      pos 13238
      pos 13254
      pos 13321
      pos 13434
      pos 13446
      pos 13455
      pos 13471
      pos 13520
      pos 13532
      pos 13553
      pos 13569
      pos 13616
      pos 13624
      pos 13636
      pos 13645
      pos 13661
      pos 13714
      pos 13726
      pos 13747
      pos 13763
      pos 13820
      pos 13836
      pos 13892
      pos 13908
      pos 14016
      pos 14021
      pos 14032
      pos 14048
      pos 14118
      pos 14161
      pos 14177
      pos 14225
      pos 14231
      pos 14241
      pos 14277
      pos 14290
      pos 14312
      pos 14332
      pos 14351
      pos 14405
      pos 14415
      pos 14467
      pos 14491
      pos 14527
      pos 14543
      pos 14571
      pos 14581
      pos 14633
      pos 14657
      pos 14693
      pos 14717
      pos 14741
      pos 15464
      pos 15532
      pos 15578
      pos 15659
      pos 15683
      pos 15711
      pos 15753
      pos 15783
      pos 15875
      pos 16014
      pos 16026
      pos 16047
      pos 16095
      pos 16108
      pos 16161
      pos 16181
      pos 16194
      pos 16287
      pos 16294
      pos 16338
      pos 16394
      pos 16402
      pos 16427
      pos 16443
      pos 16457
      pos 16540
      pos 16556
      pos 16568
      pos 16596
      pos 16627
      pos 16663
      pos 16686
      pos 16800
      pos 16851
      pos 16927
      pos 16930
      pos 16964
      pos 17048
      pos 17200
      pos 17311
      pos 17324
      pos 17344
      pos 17363
      pos 17423
      pos 17434
      pos 17443
      pos 17457
      pos 17465
    doc 1
      freq 209
      pos 46
      pos 74
      pos 88
      pos 92
      pos 194
      pos 212
      pos 219
      pos 289
      pos 295
      pos 470
      pos 502
      pos 622
      pos 673
      pos 690
      pos 711
      pos 732
      pos 773
      pos 802
      pos 864
      pos 906
      pos 937
      pos 957
      pos 969
      pos 1115
      pos 1152
      pos 1156
      pos 1256
      pos 1279
      pos 1291
      pos 1500
      pos 1527
      pos 1547
      pos 1559
      pos 1725
      pos 1753
      pos 1799
      pos 1827
      pos 1881
      pos 1889
      pos 1923
      pos 1931
      pos 1957
      pos 2019
      pos 2034
      pos 2047
      pos 2114
      pos 2162
      pos 2196
      pos 2199
      pos 2239
      pos 2434
      pos 2515
      pos 2545
      pos 2583
      pos 2637
      pos 2678
      pos 2793
      pos 2798
      pos 2837
      pos 2854
      pos 2863
      pos 2947
      pos 2962
      pos 2998
      pos 3005
      pos 3027
      pos 3073
      pos 3093
      pos 3145
      pos 3151
      pos 3183
      pos 3211
      pos 3216
      pos 3229
      pos 3253
      pos 3272
      pos 3302
      pos 3319
      pos 3333
      pos 3340
      pos 3365
      pos 3368
      pos 3457
      pos 3483
      pos 3512
      pos 3525
      pos 3550
      pos 3565
      pos 3715
      pos 3729
      pos 3732
      pos 3765
      pos 3791
      pos 3821
      pos 3868
      pos 3881
      pos 3890
      pos 3914
      pos 3934
      pos 3941
      pos 3986
      pos 4056
      pos 4134
      pos 4167
      pos 4219
      pos 4334
      pos 4367
      pos 4448
      pos 4532
      pos 4548
      pos 4555
      pos 4671
      pos 4677
      pos 4780
      pos 4786
      pos 4799
      pos 4804
      pos 4809
      pos 4834
      pos 4881
      pos 4923
      pos 4940
      pos 5058
      pos 5131
      pos 5181
      pos 5205
      pos 5228
      pos 5360
      pos 5372
      pos 5447
      pos 5477
      pos 5569
      pos 5623
      pos 5671
      pos 5811
      pos 5928
      pos 5957
      pos 5997
      pos 6104
      pos 6117
      pos 6158
      pos 6203
      pos 6324
      pos 6326
      pos 6387
      pos 6421
      pos 6439
      pos 6459
      pos 6489
      pos 6571
      pos 6611
      pos 6676
      pos 6712
      pos 7002
      pos 7102
      pos 7252
      pos 7464
      pos 7564
      pos 7567
      pos 7597
      pos 7682
      pos 7717
      pos 7760
      pos 7810
      pos 7947
      pos 7967
      pos 7997
      pos 8024
      pos 8159
      pos 8338
      pos 8384
      pos 8414
      pos 8421
      pos 8496
      pos 8503
      pos 8514
      pos 8521
      pos 8551
      pos 8583
      pos 8611
      pos 8618
      pos 8633
      pos 8644
      pos 8663
      pos 8668
      pos 8678
      pos 8696
      pos 8741
      pos 8770
      pos 8794
      pos 8810
      pos 8822
      pos 8842
      pos 8850
      pos 8860
      pos 8879
      pos 9039
      pos 9063
      pos 9085
      pos 9112
      pos 9692
      pos 9705
      pos 9725
      pos 9744
      pos 9804
      pos 9815
      pos 9824
      pos 9838
      pos 9846
    doc 2
      freq 161
      pos 23
      pos 41
      pos 45
      pos 72
      pos 108
      pos 113
      pos 187
      pos 221
      pos 326
      pos 347
      pos 385
      pos 498
      pos 509
      pos 522
      pos 532
      pos 669
      pos 710
      pos 743
      pos 840
      pos 988
      pos 1000
      pos 1053
      pos 1121
      pos 1222
      pos 1253
      pos 1269
      pos 1319
      pos 1350
      pos 1427
      pos 1435
      pos 1451
      pos 1528
      pos 1550
      pos 1574
      pos 1580
      pos 1582
      pos 1594
      pos 1604
      pos 1620
      pos 1702
      pos 1710
      pos 1727
      pos 1745
      pos 1754
      pos 1808
      pos 1815
      pos 1914
      pos 1952
      pos 1969
      pos 2012
      pos 2038
      pos 2054
      pos 2066
      pos 2071
      pos 2111
      pos 2123
      pos 2129
      pos 2186
      pos 2238
      pos 2342
      pos 2393
      pos 2856
      pos 2862
      pos 2866
      pos 2907
      pos 2928
      pos 2998
      pos 3214
      pos 3231
      pos 3250
      pos 3318
      pos 3360
      pos 3376
      pos 3392
      pos 3416
      pos 3539
      pos 3553
      pos 3574
      pos 3584
      pos 3603
      pos 3642
      pos 3705
      pos 3740
      pos 3750
      pos 3768
      pos 3777
      pos 3815
      pos 3900
      pos 3982
      pos 4043
      pos 4073
      pos 4080
      pos 4128
      pos 4137
      pos 4152
      pos 4169
      pos 4214
      pos 4233
      pos 4240
      pos 4264
      pos 4283
      pos 4308
      pos 4320
      pos 4338
      pos 4373
      pos 4396
      pos 4479
      pos 4485
      pos 4504
      pos 4523
      pos 4533
      pos 4581
      pos 4607
      pos 4616
      pos 4708
      pos 4720
      pos 4725
      pos 4727
      pos 4736
      pos 4738
      pos 4762
      pos 4807
      pos 4860
      pos 4879
      pos 4923
      pos 4959
      pos 4997
      pos 5013
      pos 5033
      pos 5106
      pos 5112
      pos 5121
      pos 5135
      pos 5144
      pos 5183
      pos 5369
      pos 5380
      pos 5387
      pos 5570
      pos 5618
      pos 5678
      pos 5706
      pos 5855
      pos 5989
      pos 6047
      pos 6058
      pos 6060
      pos 6085
      pos 6089
      pos 6157
      pos 6171
      pos 6345
      pos 6489
      pos 6502
      pos 6522
      pos 6541
      pos 6601
      pos 6612
      pos 6621
      pos 6635
      pos 6643
    doc 3
      freq 152
      pos 34
      pos 40
      pos 68
      pos 82
      pos 86
      pos 136
      pos 170
      pos 177
      pos 184
      pos 313
      pos 335
      pos 410
      pos 432
      pos 453
      pos 506
      pos 525
      pos 539
      pos 582
      pos 698
      pos 714
      pos 717
      pos 762
      pos 771
      pos 811
      pos 852
      pos 863
      pos 866
      pos 963
      pos 1041
      pos 1052
      pos 1076
      pos 1079
      pos 1125
      pos 1231
      pos 1348
      pos 1386
      pos 1389
      pos 1427
      pos 1498
      pos 1518
      pos 1539
      pos 1566
      pos 1649
      pos 1659
      pos 1672
      pos 1675
      pos 1745
      pos 1767
      pos 1780
      pos 1907
      pos 1966
      pos 2040
      pos 2119
      pos 2314
      pos 2368
      pos 2430
      pos 2456
      pos 2624
      pos 2645
      pos 2667
      pos 2825
      pos 2853
      pos 2864
      pos 2883
      pos 2889
      pos 2896
      pos 2926
      pos 2939
      pos 2971
      pos 3036
      pos 3048
      pos 3059
      pos 3079
      pos 3129
      pos 3138
      pos 3209
      pos 3297
      pos 3338
      pos 3388
      pos 3424
      pos 3449
      pos 3577
      pos 3597
      pos 3618
      pos 3693
      pos 3736
      pos 3796
      pos 3812
      pos 3820
      pos 3837
      pos 3845
      pos 3888
      pos 3892
      pos 3909
      pos 3930
      pos 3946
      pos 3950
      pos 3957
      pos 4012
      pos 4019
      pos 4025
      pos 4076
      pos 4099
      pos 4111
      pos 4134
      pos 4139
      pos 4142
      pos 4152
      pos 4171
      pos 4275
      pos 4300
      pos 4561
      pos 4685
      pos 4742
      pos 4835
      pos 4939
      pos 5004
      pos 5023
      pos 5039
      pos 5070
      pos 5174
      pos 5200
      pos 5247
      pos 5273
      pos 5307
      pos 5397
      pos 5444
      pos 5485
      pos 5574
      pos 5577
      pos 5590
      pos 5599
      pos 5618
      pos 5627
      pos 5665
      pos 5673
      pos 5676
      pos 5791
      pos 5816
      pos 5857
      pos 5861
      pos 5864
      pos 5947
      pos 6041
      pos 6054
      pos 6074
      pos 6093
      pos 6153
      pos 6164
      pos 6173
      pos 6187
      pos 6195
    doc 4
      freq 155
      pos 42
      pos 70
      pos 84
      pos 88
      pos 107
      pos 110
      pos 149
      pos 230
      pos 304
      pos 319
      pos 326
      pos 329
      pos 389
      pos 506
      pos 559
      pos 633
      pos 641
      pos 661
      pos 679
      pos 709
      pos 798
      pos 827
      pos 891
      pos 906
      pos 916
      pos 1019
      pos 1024
      pos 1034
      pos 1102
      pos 1120
      pos 1128
      pos 1178
      pos 1221
      pos 1242
      pos 1248
      pos 1264
      pos 1269
      pos 1287
      pos 1310
      pos 1381
      pos 1421
      pos 1442
      pos 1504
      pos 1553
      pos 1566
      pos 1581
      pos 1622
      pos 1642
      pos 1713
      pos 1844
      pos 1860
      pos 1873
      pos 1879
      pos 1881
      pos 1901
      pos 1915
      pos 1990
      pos 2134
      pos 2159
      pos 2182
      pos 2289
      pos 2377
      pos 2396
      pos 2405
      pos 2438
      pos 2455
      pos 2466
      pos 2488
      pos 2537
      pos 2682
      pos 2696
      pos 2800
      pos 2825
      pos 2851
      pos 2884
      pos 2897
      pos 2915
      pos 3045
      pos 3070
      pos 3124
      pos 3155
      pos 3281
      pos 3306
      pos 3352
      pos 3370
      pos 3426
      pos 3452
      pos 3460
      pos 3479
      pos 3483
      pos 3488
      pos 3501
      pos 3657
      pos 3770
      pos 3868
      pos 3889
      pos 3921
      pos 4006
      pos 4026
      pos 4076
      pos 4123
      pos 4154
      pos 4204
      pos 4247
      pos 4285
      pos 4343
      pos 4360
      pos 4380
      pos 4398
      pos 4415
      pos 4443
      pos 4451
      pos 4468
      pos 4488
      pos 4548
      pos 4563
      pos 4604
      pos 4606
      pos 4616
      pos 4637
      pos 4640
      pos 4721
      pos 4730
      pos 4980
      pos 5005
      pos 5088
      pos 5138
      pos 5167
      pos 5459
      pos 5618
      pos 5644
      pos 5654
      pos 5682
      pos 5693
      pos 5711
      pos 5750
      pos 5788
      pos 5806
      pos 5831
      pos 5842
      pos 5845
      pos 5862
      pos 5934
      pos 5936
      pos 5969
      pos 5982
      pos 6196
      pos 6209
      pos 6229
      pos 6248
      pos 6308
      pos 6319
      pos 6328
      pos 6342
      pos 6350
    doc 5
      freq 122
      pos 26
      pos 54
      pos 68
      pos 72
      pos 117
      pos 152
      pos 190
      pos 210
      pos 222
      pos 255
      pos 315
      pos 403
      pos 427
      pos 447
      pos 466
      pos 544
      pos 573
      pos 578
      pos 673
      pos 714
      pos 723
      pos 755
      pos 762
      pos 893
      pos 942
      pos 979
      pos 1085
      pos 1100
      pos 1108
      pos 1114
      pos 1119
      pos 1205
      pos 1272
      pos 1279
      pos 1314
      pos 1317
      pos 1322
      pos 1343
      pos 1367
      pos 1370
      pos 1380
      pos 1411
      pos 1430
      pos 1440
      pos 1452
      pos 1459
      pos 1516
      pos 1523
      pos 1529
      pos 1551
      pos 1636
      pos 1681
      pos 1727
      pos 1772
      pos 1784
      pos 1839
      pos 1848
      pos 1860
      pos 1922
      pos 1937
      pos 1945
      pos 1967
      pos 1997
      pos 2005
      pos 2140
      pos 2199
      pos 2201
      pos 2216
      pos 2265
      pos 2279
      pos 2304
      pos 2322
      pos 2441
      pos 2497
      pos 2539
      pos 2603
      pos 2666
      pos 2698
      pos 2717
      pos 2746
      pos 2758
      pos 2812
      pos 2825
      pos 2872
      pos 2966
      pos 2981
      pos 2990
      pos 3058
      pos 3069
      pos 3106
      pos 3131
      pos 3144
      pos 3158
      pos 3166
      pos 3184
      pos 3212
      pos 3232
      pos 3267
      pos 3283
      pos 3460
      pos 3479
      pos 3537
      pos 3635
      pos 3674
      pos 3688
      pos 3733
      pos 3849
      pos 3879
      pos 3896
      pos 4081
      pos 4218
      pos 4274
      pos 4383
      pos 4526
      pos 4539
      pos 4559
      pos 4578
      pos 4638
      pos 4649
      pos 4658
      pos 4672
      pos 4680
    doc 6
      freq 129
      pos 26
      pos 44
      pos 48
      pos 72
      pos 155
      pos 228
      pos 233
      pos 312
      pos 318
      pos 329
      pos 364
      pos 374
      pos 420
      pos 442
      pos 465
      pos 485
      pos 500
      pos 516
      pos 521
      pos 529
      pos 550
      pos 635
      pos 657
      pos 667
      pos 680
      pos 708
      pos 717
      pos 731
      pos 816
      pos 840
      pos 845
      pos 850
      pos 862
      pos 877
      pos 907
      pos 920
      pos 937
      pos 1044
      pos 1070
      pos 1148
      pos 1175
      pos 1183
      pos 1189
      pos 1215
      pos 1271
      pos 1296
      pos 1305
      pos 1318
      pos 1337
      pos 1361
      pos 1366
      pos 1368
      pos 1376
      pos 1405
      pos 1424
      pos 1441
      pos 1449
      pos 1497
      pos 1578
      pos 1582
      pos 1597
      pos 1675
      pos 1694
      pos 1706
      pos 1758
      pos 1794
      pos 1809
      pos 1815
      pos 1824
      pos 1838
      pos 1840
      pos 1861
      pos 1865
      pos 1930
      pos 1960
      pos 1962
      pos 1984
      pos 1998
      pos 2047
      pos 2051
      pos 2129
      pos 2150
      pos 2202
      pos 2212
      pos 2277
      pos 2280
      pos 2301
      pos 2307
      pos 2321
      pos 2370
      pos 2394
      pos 2409
      pos 2431
      pos 2452
      pos 2487
      pos 2530
      pos 2707
      pos 2781
      pos 2799
      pos 2805
      pos 2810
      pos 2825
      pos 2924
      pos 2942
      pos 2945
      pos 2955
      pos 3094
      pos 3100
      pos 3109
      pos 3115
      pos 3120
      pos 3125
      pos 3131
      pos 3136
      pos 3141
      pos 3146
      pos 3152
      pos 3156
      pos 3162
      pos 3171
      pos 3326
      pos 3339
      pos 3359
      pos 3378
      pos 3438
      pos 3449
      pos 3458
      pos 3472
      pos 3480
    doc 7
      freq 88
      pos 22
      pos 37
      pos 55
      pos 59
      pos 98
      pos 113
      pos 170
      pos 178
      pos 215
      pos 226
      pos 234
      pos 252
      pos 264
      pos 292
      pos 307
      pos 312
      pos 339
      pos 364
      pos 377
      pos 419
      pos 427
      pos 484
      pos 546
      pos 565
      pos 598
      pos 697
      pos 732
      pos 769
      pos 877
      pos 886
      pos 962
      pos 986
      pos 1023
      pos 1056
      pos 1105
      pos 1118
      pos 1168
      pos 1183
      pos 1238
      pos 1288
      pos 1374
      pos 1405
      pos 1439
      pos 1470
      pos 1483
      pos 1511
      pos 1520
      pos 1540
      pos 1558
      pos 1627
      pos 1676
      pos 1688
      pos 1712
      pos 1775
      pos 1778
      pos 1881
      pos 1971
      pos 1993
      pos 2008
      pos 2069
      pos 2159
      pos 2287
      pos 2295
      pos 2305
      pos 2312
      pos 2322
      pos 2331
      pos 2341
      pos 2350
      pos 2406
      pos 2442
      pos 2474
      pos 2568
      pos 2619
      pos 2633
      pos 2692
      pos 2753
      pos 2777
      pos 2875
      pos 3031
      pos 3044
      pos 3064
      pos 3083
      pos 3143
      pos 3154
      pos 3163
      pos 3177
      pos 3185
    doc 8
      freq 44
      pos 30
      pos 53
      pos 106
      pos 113
      pos 196
      pos 304
      pos 349
      pos 362
      pos 367
      pos 405
      pos 416
      pos 490
      pos 602
      pos 818
      pos 921
      pos 938
      pos 980
      pos 1023
      pos 1105
      pos 1147
      pos 1246
      pos 1274
      pos 1328
      pos 1427
      pos 1469
      pos 1518
      pos 1526
      pos 1568
      pos 1634
      pos 1652
      pos 1706
      pos 1914
      pos 1952
      pos 1974
      pos 1999
      pos 2248
      pos 2261
      pos 2281
      pos 2300
      pos 2360
      pos 2371
      pos 2380
      pos 2394
      pos 2402
    doc 9
      freq 50
      pos 28
      pos 56
      pos 70
      pos 74
      pos 115
      pos 189
      pos 204
      pos 208
      pos 249
      pos 302
      pos 335
      pos 339
      pos 419
      pos 480
      pos 491
      pos 517
      pos 552
      pos 577
      pos 666
      pos 738
      pos 833
      pos 855
      pos 885
      pos 902
      pos 907
      pos 912
      pos 991
      pos 1064
      pos 1178
      pos 1185
      pos 1210
      pos 1280
      pos 1286
      pos 1310
      pos 1345
      pos 1397
      pos 1453
      pos 1483
      pos 1597
      pos 1603
      pos 1631
      pos 1893
      pos 1906
      pos 1926
      pos 1945
      pos 2005
      pos 2016
      pos 2025
      pos 2039
      pos 2047
    doc 10
      freq 328
      pos 31
      pos 59
      pos 73
      pos 77
      pos 108
      pos 130
      pos 163
      pos 179
      pos 192
      pos 273
      pos 366
      pos 368
      pos 430
      pos 443
      pos 483
      pos 504
      pos 507
      pos 516
      pos 661
      pos 715
      pos 741
      pos 755
      pos 769
      pos 793
      pos 811
      pos 828
      pos 831
      pos 846
      pos 934
      pos 944
      pos 947
      pos 1007
      pos 1013
      pos 1022
      pos 1057
      pos 1112
      pos 1169
      pos 1198
      pos 1220
      pos 1224
      pos 1238
      pos 1322
      pos 1336
      pos 1384
      pos 1471
      pos 1514
      pos 1536
      pos 1541
      pos 1558
      pos 1574
      pos 1667
      pos 1686
      pos 1735
      pos 1759
      pos 1775
      pos 1787
      pos 1804
      pos 1809
      pos 1832
      pos 1896
      pos 1957
      pos 1961
      pos 1969
      pos 1987
      pos 2047
      pos 2139
      pos 2151
      pos 2306
      pos 2348
      pos 2396
      pos 2446
      pos 2503
      pos 2532
      pos 2558
      pos 2614
      pos 2705
      pos 2720
      pos 2723
      pos 2735
      pos 2769
      pos 2785
      pos 2819
      pos 2852
      pos 2858
      pos 2901
      pos 2931
      pos 3028
      pos 3042
      pos 3067
      pos 3103
      pos 3172
      pos 3251
      pos 3258
      pos 3278
      pos 3357
      pos 3359
      pos 3402
      pos 3445
      pos 3453
      pos 3541
      pos 3553
      pos 3598
      pos 3638
      pos 3661
      pos 3671
      pos 3769
      pos 3827
      pos 3830
      pos 3836
      pos 3852
      pos 3903
      pos 3906
      pos 3945
      pos 4037
      pos 4274
      pos 4286
      pos 4295
      pos 4363
      pos 4452
      pos 4508
      pos 4538
      pos 4586
      pos 4617
      pos 4639
      pos 4668
      pos 4671
      pos 4704
      pos 4707
      pos 4777
      pos 4859
      pos 4867
      pos 4875
      pos 4883
      pos 4911
      pos 4920
      pos 4950
      pos 5043
      pos 5095
      pos 5123
      pos 5147
      pos 5167
      pos 5207
      pos 5232
      pos 5292
      pos 5310
      pos 5434
      pos 5479
      pos 5497
      pos 5512
      pos 5557
      pos 5560
      pos 5569
      pos 5586
      pos 5592
      pos 5599
      pos 5618
      pos 5631
      pos 5714
      pos 5779
      pos 5906
      pos 5952
      pos 5959
      pos 5979
      pos 6021
      pos 6080
      pos 6103
      pos 6112
      pos 6289
      pos 6444
      pos 6476
      pos 6724
      pos 6752
      pos 6796
      pos 6931
      pos 7048
      pos 7179
      pos 7226
      pos 7421
      pos 7443
      pos 7459
      pos 7470
      pos 7473
      pos 7501
      pos 7532
      pos 7681
      pos 7752
      pos 7849
      pos 7866
      pos 7883
      pos 7887
      pos 7892
      pos 7922
      pos 7952
      pos 7978
      pos 7995
      pos 8058
      pos 8085
      pos 8117
      pos 8134
      pos 8141
      pos 8176
      pos 8210
      pos 8235
      pos 8288
      pos 8326
      pos 8336
      pos 8353
      pos 8356
      pos 8363
      pos 8374
      pos 8381
      pos 8391
      pos 8447
      pos 8458
      pos 8491
      pos 8521
      pos 8524
      pos 8552
      pos 8594
      pos 8616
      pos 8657
      pos 8660
      pos 8829
      pos 8850
      pos 8886
      pos 8902
      pos 9015
      pos 9023
      pos 9049
      pos 9066
      pos 9077
      pos 9107
      pos 9194
      pos 9220
      pos 9360
      pos 9396
      pos 9489
      pos 9564
      pos 9576
      pos 9581
      pos 9587
      pos 9610
      pos 9697
      pos 9749
      pos 9782
      pos 9787
      pos 9796
      pos 9840
      pos 9846
      pos 9869
      pos 9920
      pos 9951
      pos 10129
      pos 10157
      pos 10170
      pos 10213
      pos 10250
      pos 10343
      pos 10385
      pos 10393
      pos 10404
      pos 10439
      pos 10530
      pos 10572
      pos 10589
      pos 10603
      pos 10659
      pos 10668
      pos 10709
      pos 10771
      pos 10800
      pos 10809
      pos 10818
      pos 10843
      pos 10873
      pos 10902
      pos 10935
      pos 10995
      pos 11011
      pos 11025
      pos 11082
      pos 11125
      pos 11226
      pos 11275
      pos 11293
      pos 11303
      pos 11326
      pos 11374
      pos 11398
      pos 11409
      pos 11419
      pos 11457
      pos 11467
      pos 11765
      pos 11977
      pos 12060
      pos 12147
      pos 12161
      pos 12181
      pos 12183
      pos 12196
      pos 12206
      pos 12239
      pos 12252
      pos 12263
      pos 12269
      pos 12316
      pos 12325
      pos 12334
      pos 12353
      pos 12849
      pos 12921
      pos 12927
      pos 12942
      pos 12948
      pos 12985
      pos 13005
      pos 13009
      pos 13072
      pos 13554
      pos 13567
      pos 13587
      pos 13606
      pos 13666
      pos 13677
      pos 13686
      pos 13700
      pos 13708
    doc 11
      freq 110
      pos 39
      pos 57
      pos 61
      pos 80
      pos 96
      pos 145
      pos 152
      pos 165
      pos 316
      pos 475
      pos 547
      pos 571
      pos 584
      pos 598
      pos 739
      pos 760
      pos 786
      pos 804
      pos 844
      pos 861
      pos 879
      pos 925
      pos 939
      pos 948
      pos 989
      pos 1024
      pos 1059
      pos 1142
      pos 1145
      pos 1161
      pos 1172
      pos 1263
      pos 1302
      pos 1320
      pos 1374
      pos 1385
      pos 1405
      pos 1583
      pos 1592
      pos 1629
      pos 1644
      pos 1687
      pos 1700
      pos 1797
      pos 2005
      pos 2051
      pos 2086
      pos 2172
      pos 2183
      pos 2333
      pos 2406
      pos 2415
      pos 2461
      pos 2806
      pos 3257
      pos 3469
      pos 3748
      pos 4214
      pos 4217
      pos 4229
      pos 4365
      pos 4442
      pos 4555
      pos 5095
      pos 5564
      pos 5713
      pos 5906
      pos 5921
      pos 5968
      pos 6072
      pos 6526
      pos 7190
      pos 7328
      pos 7340
      pos 7436
      pos 7574
      pos 7682
      pos 7798
      pos 8285
      pos 8443
      pos 8550
      pos 8713
      pos 8790
      pos 8804
      pos 8895
      pos 9006
      pos 9317
      pos 9338
      pos 9358
      pos 9402
      pos 9427
      pos 9459
      pos 9511
      pos 9540
      pos 9555
      pos 9558
      pos 9733
      pos 9748
      pos 9753
      pos 9770
      pos 10590
      pos 10715
      pos 10728
      pos 10748
      pos 10767
      pos 10827
      pos 10838
      pos 10847
      pos 10861
      pos 10869
    doc 12
      freq 191
      pos 29
      pos 47
      pos 51
      pos 81
      pos 86
      pos 131
      pos 146
      pos 161
      pos 218
      pos 227
      pos 255
      pos 259
      pos 288
      pos 339
      pos 378
      pos 426
      pos 459
      pos 470
      pos 488
      pos 530
      pos 548
      pos 587
      pos 620
      pos 661
      pos 808
      pos 853
      pos 873
      pos 917
      pos 1060
      pos 1064
      pos 1101
      pos 1192
      pos 1240
      pos 1264
      pos 1357
      pos 1366
      pos 1437
      pos 1457
      pos 1509
      pos 1599
      pos 1622
      pos 1635
      pos 1651
      pos 1667
      pos 1677
      pos 1711
      pos 1740
      pos 1769
      pos 1797
      pos 1904
      pos 1909
      pos 1988
      pos 1992
      pos 2036
      pos 2040
      pos 2120
      pos 2160
      pos 2210
      pos 2238
      pos 2361
      pos 2492
      pos 2510
      pos 2539
      pos 2588
      pos 2595
      pos 2659
      pos 2729
      pos 2766
      pos 2776
      pos 2794
      pos 2803
      pos 2815
      pos 2887
      pos 2909
      pos 2924
      pos 3001
      pos 3275
      pos 3300
      pos 3409
      pos 3445
      pos 3494
      pos 3519
      pos 3642
      pos 3657
      pos 3670
      pos 3769
      pos 3871
      pos 3928
      pos 3938
      pos 3963
      pos 3979
      pos 4003
      pos 4012
      pos 4019
      pos 4042
      pos 4062
      pos 4068
      pos 4212
      pos 4244
      pos 4282
      pos 4308
      pos 4321
      pos 4329
      pos 4446
      pos 4455
      pos 4812
      pos 4827
      pos 4833
      pos 4867
      pos 4933
      pos 4948
      pos 4957
      pos 4991
      pos 5022
      pos 5040
      pos 5120
      pos 5132
      pos 5267
      pos 5327
      pos 5373
      pos 5554
      pos 5597
      pos 5640
      pos 5649
      pos 5741
      pos 5746
      pos 5770
      pos 5879
      pos 6025
      pos 6169
      pos 6184
      pos 6224
      pos 6289
      pos 6384
      pos 6528
      pos 6573
      pos 6576
      pos 6581
      pos 6621
      pos 6737
      pos 6798
      pos 6936
      pos 7062
      pos 7148
      pos 7162
      pos 7361
      pos 7445
      pos 7503
      pos 7849
      pos 7867
      pos 7916
      pos 7957
      pos 8045
      pos 8076
      pos 8115
      pos 8123
      pos 8172
      pos 8229
      pos 8350
      pos 8368
      pos 8389
      pos 8455
      pos 8518
      pos 8527
      pos 8535
      pos 8544
      pos 8601
      pos 8658
      pos 8669
      pos 8720
      pos 8729
      pos 8760
      pos 8762
      pos 8930
      pos 8939
      pos 9024
      pos 9057
      pos 9070
      pos 9201
      pos 9211
      pos 9283
      pos 9395
      pos 9565
      pos 9578
      pos 9598
      pos 9617
      pos 9677
      pos 9688
      pos 9697
      pos 9711
      pos 9719
    doc 13
      freq 239
      pos 23
      pos 38
      pos 56
      pos 60
      pos 108
      pos 133
      pos 145
      pos 212
      pos 246
      pos 326
      pos 385
      pos 435
      pos 488
      pos 491
      pos 501
      pos 509
      pos 581
      pos 599
      pos 621
      pos 657
      pos 687
      pos 698
      pos 720
      pos 732
      pos 819
      pos 835
      pos 862
      pos 870
      pos 941
      pos 969
      pos 1008
      pos 1025
      pos 1056
      pos 1095
      pos 1117
      pos 1171
      pos 1232
      pos 1237
      pos 1250
      pos 1271
      pos 1274
      pos 1285
      pos 1292
      pos 1305
      pos 1324
      pos 1330
      pos 1406
      pos 1423
      pos 1430
      pos 1487
      pos 1501
      pos 1509
      pos 1550
      pos 1602
      pos 1614
      pos 1650
      pos 1662
      pos 1666
      pos 1732
      pos 1737
      pos 1842
      pos 1845
      pos 1868
      pos 1879
      pos 1891
      pos 1942
      pos 1949
      pos 2023
      pos 2064
      pos 2078
      pos 2107
      pos 2119
      pos 2131
      pos 2141
      pos 2214
      pos 2222
      pos 2282
      pos 2296
      pos 2302
      pos 2320
      pos 2337
      pos 2351
      pos 2361
      pos 2371
      pos 2374
      pos 2384
      pos 2420
      pos 2506
      pos 2528
      pos 2583
      pos 2678
      pos 2743
      pos 2759
      pos 2770
      pos 2775
      pos 2795
      pos 2851
      pos 2876
      pos 2893
      pos 2946
      pos 2987
      pos 3015
      pos 3027
      pos 3038
      pos 3055
      pos 3062
      pos 3079
      pos 3092
      pos 3123
      pos 3183
      pos 3215
      pos 3225
      pos 3242
      pos 3269
      pos 3279
      pos 3317
      pos 3328
      pos 3333
      pos 3350
      pos 3399
      pos 3406
      pos 3449
      pos 3466
      pos 3497
      pos 3502
      pos 3525
      pos 3544
      pos 3577
      pos 3588
      pos 3626
      pos 3638
      pos 3723
      pos 3812
      pos 3831
      pos 3840
      pos 3882
      pos 3953
      pos 3986
      pos 3995
      pos 4011
      pos 4016
      pos 4121
      pos 4137
      pos 4171
      pos 4178
      pos 4194
      pos 4247
      pos 4346
      pos 4383
      pos 4394
      pos 4405
      pos 4440
      pos 4458
      pos 4473
      pos 4737
      pos 4776
      pos 4802
      pos 4814
      pos 4868
      pos 4885
      pos 4891
      pos 4897
      pos 4946
      pos 4983
      pos 5031
      pos 5070
      pos 5077
      pos 5082
      pos 5108
      pos 5156
      pos 5180
      pos 5196
      pos 5199
      pos 5210
      pos 5213
      pos 5245
      pos 5283
      pos 5339
      pos 5366
      pos 5418
      pos 5426
      pos 5440
      pos 5452
      pos 5464
      pos 5498
      pos 5518
      pos 5574
      pos 5600
      pos 5610
      pos 5633
      pos 5775
      pos 5823
      pos 5826
      pos 5840
      pos 5843
      pos 5852
      pos 5866
      pos 5880
      pos 5883
      pos 5892
      pos 5909
      pos 5932
      pos 5937
      pos 5950
      pos 5974
      pos 5989
      pos 5992
      pos 6040
      pos 6074
      pos 6090
      pos 6104
      pos 6166
      pos 6222
      pos 6226
      pos 6247
      pos 6282
      pos 6362
      pos 6393
      pos 6397
      pos 6451
      pos 6482
      pos 6559
      pos 6585
      pos 6592
      pos 6603
      pos 6664
      pos 6697
      pos 6871
      pos 7043
      pos 7060
      pos 7180
      pos 7193
      pos 7213
      pos 7232
      pos 7292
      pos 7303
      pos 7312
      pos 7326
      pos 7334
    doc 14
      freq 180
      pos 17
      pos 24
      pos 44
      pos 55
      pos 82
      pos 106
      pos 119
      pos 137
      pos 144
      pos 155
      pos 162
      pos 181
      pos 195
      pos 204
      pos 232
      pos 241
      pos 250
      pos 258
      pos 285
      pos 292
      pos 319
      pos 364
      pos 380
      pos 399
      pos 443
      pos 492
      pos 507
      pos 538
      pos 544
      pos 581
      pos 674
      pos 688
      pos 706
      pos 715
      pos 721
      pos 723
      pos 751
      pos 754
      pos 758
      pos 789
      pos 810
      pos 817
      pos 863
      pos 879
      pos 887
      pos 889
      pos 903
      pos 935
      pos 982
      pos 1002
      pos 1044
      pos 1082
      pos 1110
      pos 1130
      pos 1140
      pos 1142
      pos 1192
      pos 1203
      pos 1207
      pos 1243
      pos 1262
      pos 1275
      pos 1278
      pos 1284
      pos 1303
      pos 1315
      pos 1318
      pos 1327
      pos 1330
      pos 1342
      pos 1363
      pos 1382
      pos 1403
      pos 1425
      pos 1442
      pos 1445
      pos 1449
      pos 1476
      pos 1494
      pos 1510
      pos 1538
      pos 1559
      pos 1580
      pos 1602
      pos 1618
      pos 1634
      pos 1654
      pos 1696
      pos 1741
      pos 1743
      pos 1756
      pos 1770
      pos 1780
      pos 1841
      pos 1862
      pos 1883
      pos 1907
      pos 1963
      pos 1985
      pos 2006
      pos 2023
      pos 2047
      pos 2058
      pos 2098
      pos 2112
      pos 2117
      pos 2172
      pos 2192
      pos 2202
      pos 2271
      pos 2323
      pos 2328
      pos 2349
      pos 2361
      pos 2370
      pos 2394
      pos 2415
      pos 2428
      pos 2439
      pos 2458
      pos 2472
      pos 2503
      pos 2540
      pos 2581
      pos 2597
      pos 2604
      pos 2681
      pos 2693
      pos 2698
      pos 2702
      pos 2733
      pos 2739
      pos 2753
      pos 2764
      pos 2805
      pos 2837
      pos 2851
      pos 2863
      pos 2869
      pos 2893
      pos 2915
      pos 2950
      pos 2954
      pos 2961
      pos 3223
      pos 3225
      pos 3235
      pos 3239
      pos 3243
      pos 3273
      pos 3829
      pos 3831
      pos 3856
      pos 4146
      pos 4153
      pos 4168
      pos 4435
      pos 4613
      pos 4875
      pos 4881
      pos 4994
      pos 5034
      pos 5129
      pos 5135
      pos 5181
      pos 5279
      pos 5286
      pos 5294
      pos 5297
      pos 5319
      pos 5420
      pos 5646
      pos 5659
      pos 5679
      pos 5698
      pos 5758
      pos 5769
      pos 5778
      pos 5792
      pos 5800
    doc 15
      freq 80
      pos 10
      pos 21
      pos 37
      pos 55
      pos 59
      pos 109
      pos 143
      pos 201
      pos 274
      pos 316
      pos 341
      pos 347
      pos 428
      pos 575
      pos 654
      pos 719
      pos 735
      pos 920
      pos 931
      pos 1005
      pos 1136
      pos 1186
      pos 1193
      pos 1326
      pos 1375
      pos 1413
      pos 1580
      pos 1604
      pos 1630
      pos 1655
      pos 1677
      pos 1684
      pos 2001
      pos 2029
      pos 2073
      pos 2158
      pos 2192
      pos 2278
      pos 2382
      pos 2481
      pos 2484
      pos 2527
      pos 2567
      pos 2579
      pos 2600
      pos 2649
      pos 2724
      pos 2797
      pos 2811
      pos 2813
      pos 2850
      pos 2958
      pos 3044
      pos 3153
      pos 3176
      pos 3178
      pos 3217
      pos 3231
      pos 3236
      pos 3515
      pos 3518
      pos 3535
      pos 3659
      pos 3670
      pos 3708
      pos 3710
      pos 3873
      pos 3875
      pos 4019
      pos 4022
      pos 4050
      pos 4165
      pos 4178
      pos 4198
      pos 4217
      pos 4277
      pos 4288
      pos 4297
      pos 4311
      pos 4319
    doc 16
      freq 59
      pos 27
      pos 55
      pos 69
      pos 73
      pos 116
      pos 122
      pos 138
      pos 202
      pos 206
      pos 236
      pos 249
      pos 387
      pos 394
      pos 414
      pos 428
      pos 440
      pos 455
      pos 499
      pos 521
      pos 555
      pos 646
      pos 691
      pos 726
      pos 734
      pos 769
      pos 794
      pos 846
      pos 855
      pos 881
      pos 931
      pos 942
      pos 966
      pos 982
      pos 1004
      pos 1033
      pos 1073
      pos 1133
      pos 1263
      pos 1436
      pos 1541
      pos 1551
      pos 1581
      pos 1621
      pos 1706
      pos 1901
      pos 2278
      pos 2299
      pos 2381
      pos 2498
      pos 2583
      pos 2776
      pos 2789
      pos 2809
      pos 2828
      pos 2888
      pos 2899
      pos 2908
      pos 2922
      pos 2930
    doc 17
      freq 58
      pos 24
      pos 52
      pos 66
      pos 70
      pos 108
      pos 141
      pos 179
      pos 223
      pos 307
      pos 313
      pos 323
      pos 338
      pos 428
      pos 553
      pos 627
      pos 630
      pos 696
      pos 703
      pos 740
      pos 791
      pos 802
      pos 945
      pos 1034
      pos 1086
      pos 1157
      pos 1213
      pos 1263
      pos 1270
      pos 1274
      pos 1406
      pos 1429
      pos 1449
      pos 1471
      pos 1486
      pos 1494
      pos 1521
      pos 1529
      pos 1562
      pos 1579
      pos 1586
      pos 1672
      pos 1703
      pos 1826
      pos 1860
      pos 1891
      pos 1922
      pos 2021
      pos 2299
      pos 2310
      pos 2500
      pos 2513
      pos 2533
      pos 2552
      pos 2612
      pos 2623
      pos 2632
      pos 2646
      pos 2654
    doc 18
      freq 67
      pos 33
      pos 61
      pos 75
      pos 79
      pos 108
      pos 132
      pos 142
      pos 150
      pos 157
      pos 264
      pos 291
      pos 341
      pos 360
      pos 370
      pos 373
      pos 413
      pos 436
      pos 450
      pos 470
      pos 479
      pos 481
      pos 487
      pos 497
      pos 500
      pos 558
      pos 602
      pos 632
      pos 685
      pos 732
      pos 751
      pos 823
      pos 904
      pos 920
      pos 995
      pos 1005
      pos 1050
      pos 1182
      pos 1196
      pos 1208
      pos 1215
      pos 1300
      pos 1311
      pos 1316
      pos 1375
      pos 1531
      pos 1555
      pos 1569
      pos 1577
      pos 1595
      pos 1644
      pos 1688
      pos 1709
      pos 1786
      pos 1801
      pos 1840
      pos 1864
      pos 2010
      pos 2053
      pos 2288
      pos 2301
      pos 2321
      pos 2340
      pos 2400
      pos 2411
      pos 2420
      pos 2434
      pos 2442
    skipList 
      level 0
        skipDoc 7
        skipDocFP 1597075
        impacts 
          impact 
            freq 88
            norm 100
          impact 
            freq 129
            norm 101
          impact 
            freq 152
            norm 107
          impact 
            freq 161
            norm 108
          impact 
            freq 209
            norm 113
          impact 
            freq 427
            norm 120
        impactsEnd 
        skipDoc 15
        skipDocFP 1618845
        impacts 
          impact 
            freq 50
            norm 95
          impact 
            freq 80
            norm 104
          impact 
            freq 180
            norm 107
          impact 
            freq 239
            norm 109
          impact 
            freq 328
            norm 116
        impactsEnd 
  term ofd2kgrmm
    doc 10
      freq 1
      pos 12680
  term ofeaqyk8rxiixjqohko
    doc 11
      freq 1
      pos 10147
  term off
    doc 0
      freq 9
      pos 1599
      pos 1647
      pos 2751
      pos 2764
      pos 4883
      pos 5640
      pos 10190
      pos 11492
      pos 16521
    doc 3
      freq 3
      pos 2148
      pos 2290
      pos 2302
    doc 12
      freq 2
      pos 8985
      pos 9033
    doc 15
      freq 1
      pos 789
  term offending
    doc 4
      freq 1
      pos 1445
  term offer
    doc 3
      freq 2
      pos 123
      pos 1275
    doc 5
      freq 1
      pos 3400
    doc 11
      freq 1
      pos 9662
    doc 15
      freq 2
      pos 746
      pos 985
  term offered
    doc 2
      freq 1
      pos 3818
    doc 9
      freq 1
      pos 495
    doc 10
      freq 1
      pos 7918
    doc 11
      freq 1
      pos 9030
    doc 12
      freq 1
      pos 2724
    doc 15
      freq 3
      pos 1138
      pos 1947
      pos 2823
  term offering
    doc 11
      freq 2
      pos 518
      pos 8969
    doc 15
      freq 2
      pos 1376
      pos 3378
  term offers
    doc 10
      freq 1
      pos 13017
  term official
    doc 0
      freq 1
      pos 60
    doc 1
      freq 1
      pos 77
    doc 2
      freq 3
      pos 3663
      pos 4022
      pos 4325
    doc 3
      freq 1
      pos 71
    doc 4
      freq 1
      pos 73
    doc 5
      freq 1
      pos 57
    doc 9
      freq 1
      pos 59
    doc 10
      freq 1
      pos 62
    doc 16
      freq 1
      pos 58
    doc 17
      freq 1
      pos 55
    doc 18
      freq 1
      pos 64
    skipList 
      level 0
        skipDoc 10
        skipDocFP 1641959
        impacts 
          impact 
            freq 1
            norm 95
          impact 
            freq 3
            norm 108
        impactsEnd 
  term offset
    doc 0
      freq 1
      pos 12682
    doc 4
      freq 1
      pos 3335
  term ofl3sato6gvcceoy4wiv7xlbgaf
    doc 11
      freq 1
      pos 9934
  term often
    doc 2
      freq 2
      pos 1135
      pos 1991
    doc 9
      freq 1
      pos 570
    doc 12
      freq 2
      pos 4267
      pos 9158
  term ofwhvznxwfc4rmon15eclpacz9
    doc 10
      freq 1
      pos 12640
  term ogazwwuop9pwh7cf57hh7i5vw3gd
    doc 10
      freq 1
      pos 12670
  term ohba
    doc 2
      freq 1
      pos 3336
  term ohhfjnvudor4seixek0o6njkhfzhclxelk4dpvuqsdsqg1
    doc 10
      freq 1
      pos 12521
  term ohlmeier
    doc 11
      freq 1
      pos 9444
  term ohta
    doc 12
      freq 2
      pos 6783
      pos 7760
  term oid
    doc 0
      freq 1
      pos 3226
    doc 17
      freq 3
      pos 950
      pos 1955
      pos 1957
  term oids
    doc 0
      freq 3
      pos 3638
      pos 4154
      pos 10996
    doc 17
      freq 1
      pos 2256
  term oifbaiakqgnmiagjacbcwgsslqabtmog0lyg0ks
    doc 11
      freq 1
      pos 10148
  term ok
    doc 11
      freq 4
      pos 463
      pos 3928
      pos 8371
      pos 8470
    doc 16
      freq 7
      pos 597
      pos 1202
      pos 1846
      pos 1927
      pos 2090
      pos 2105
      pos 2242
  term okhvzsmy42imvt
    doc 11
      freq 1
      pos 10049
  term olaf
    doc 14
      freq 1
      pos 5345
    doc 18
      freq 1
      pos 2013
  term olafur
    doc 14
      freq 1
      pos 5347
  term old
    doc 1
      freq 1
      pos 7433
    doc 2
      freq 1
      pos 739
    doc 7
      freq 3
      pos 511
      pos 1559
      pos 1780
    doc 9
      freq 3
      pos 870
      pos 883
      pos 1476
    doc 13
      freq 2
      pos 4724
      pos 5608
    doc 18
      freq 1
      pos 1926
  term older
    doc 1
      freq 1
      pos 7486
    doc 7
      freq 1
      pos 1637
    doc 10
      freq 1
      pos 5701
    doc 13
      freq 2
      pos 6564
      pos 6583
  term olivehu
    doc 11
      freq 1
      pos 10408
  term om99v9z3
    doc 11
      freq 1
      pos 10062
  term omega
    doc 1
      freq 4
      pos 9254
      pos 9258
      pos 9270
      pos 9274
    doc 3
      freq 2
      pos 4784
      pos 4788
  term omhcutxl8
    doc 11
      freq 1
      pos 10127
  term omission
    doc 10
      freq 1
      pos 9620
    doc 14
      freq 2
      pos 1268
      pos 1309
  term omit
    doc 12
      freq 2
      pos 8812
      pos 9348
  term omitted
    doc 1
      freq 1
      pos 5565
    doc 5
      freq 2
      pos 1129
      pos 2074
    doc 9
      freq 1
      pos 271
    doc 12
      freq 2
      pos 9104
      pos 9139
    doc 14
      freq 3
      pos 1199
      pos 1250
      pos 1291
  term omitting
    doc 12
      freq 5
      pos 8584
      pos 8598
      pos 8652
      pos 8819
      pos 9067
  term ompuig6ws0ahms1
    doc 11
      freq 1
      pos 9916
  term on
    doc 0
      freq 83
      pos 478
      pos 545
      pos 685
      pos 847
      pos 872
      pos 1160
      pos 1484
      pos 1597
      pos 1649
      pos 2246
      pos 2362
      pos 2505
      pos 2686
      pos 2745
      pos 3052
      pos 3152
      pos 3266
      pos 3871
      pos 4371
      pos 4792
      pos 4896
      pos 4919
      pos 5070
      pos 5373
      pos 5452
      pos 5676
      pos 5812
      pos 5845
      pos 5990
      pos 6042
      pos 6093
      pos 6171
      pos 6252
      pos 6313
      pos 6321
      pos 6523
      pos 6544
      pos 6585
      pos 6594
      pos 6619
      pos 6659
      pos 6698
      pos 6737
      pos 6856
      pos 6875
      pos 6887
      pos 6949
      pos 7000
      pos 7122
      pos 7792
      pos 7876
      pos 7885
      pos 7917
      pos 7942
      pos 8025
      pos 8230
      pos 8289
      pos 8318
      pos 8477
      pos 8539
      pos 8596
      pos 8867
      pos 8946
      pos 9028
      pos 9190
      pos 9201
      pos 9209
      pos 9271
      pos 9960
      pos 10096
      pos 10874
      pos 11235
      pos 12024
      pos 13012
      pos 14280
      pos 15843
      pos 16054
      pos 16157
      pos 16560
      pos 16778
      pos 17267
      pos 17403
      pos 17474
    doc 1
      freq 26
      pos 491
      pos 517
      pos 1271
      pos 1281
      pos 1552
      pos 1793
      pos 2025
      pos 2175
      pos 2182
      pos 2556
      pos 2565
      pos 3575
      pos 3878
      pos 4667
      pos 6394
      pos 6466
      pos 6770
      pos 7737
      pos 8027
      pos 8380
      pos 8693
      pos 8727
      pos 9170
      pos 9648
      pos 9784
      pos 9855
    doc 2
      freq 43
      pos 745
      pos 969
      pos 1095
      pos 1346
      pos 1384
      pos 1866
      pos 1934
      pos 2375
      pos 3550
      pos 3747
      pos 3897
      pos 4066
      pos 4075
      pos 4097
      pos 4133
      pos 4222
      pos 4237
      pos 4312
      pos 4449
      pos 4733
      pos 4944
      pos 5055
      pos 5064
      pos 5173
      pos 5213
      pos 5294
      pos 5298
      pos 5307
      pos 5438
      pos 5472
      pos 5533
      pos 5542
      pos 5651
      pos 5698
      pos 5712
      pos 5762
      pos 5803
      pos 5933
      pos 6118
      pos 6305
      pos 6445
      pos 6581
      pos 6652
    doc 3
      freq 51
      pos 232
      pos 681
      pos 807
      pos 886
      pos 903
      pos 1177
      pos 1183
      pos 1470
      pos 1652
      pos 1760
      pos 1792
      pos 1870
      pos 1903
      pos 1914
      pos 2047
      pos 2223
      pos 2238
      pos 2362
      pos 2479
      pos 2549
      pos 2594
      pos 2729
      pos 2758
      pos 2834
      pos 3120
      pos 3165
      pos 3194
      pos 3273
      pos 3293
      pos 3419
      pos 3452
      pos 3498
      pos 4050
      pos 4092
      pos 5035
      pos 5045
      pos 5052
      pos 5118
      pos 5134
      pos 5262
      pos 5334
      pos 5378
      pos 5409
      pos 5462
      pos 5506
      pos 5638
      pos 5669
      pos 5837
      pos 5997
      pos 6133
      pos 6204
    doc 4
      freq 14
      pos 649
      pos 1999
      pos 2705
      pos 3933
      pos 4003
      pos 4583
      pos 4668
      pos 4697
      pos 4705
      pos 4924
      pos 5769
      pos 6152
      pos 6288
      pos 6359
    doc 5
      freq 15
      pos 127
      pos 488
      pos 752
      pos 759
      pos 890
      pos 1448
      pos 1564
      pos 2164
      pos 2434
      pos 2755
      pos 3414
      pos 3475
      pos 4482
      pos 4618
      pos 4689
    doc 6
      freq 15
      pos 124
      pos 371
      pos 424
      pos 614
      pos 812
      pos 901
      pos 1432
      pos 1663
      pos 1671
      pos 2474
      pos 2537
      pos 2655
      pos 3282
      pos 3418
      pos 3489
    doc 7
      freq 16
      pos 262
      pos 289
      pos 410
      pos 535
      pos 616
      pos 639
      pos 663
      pos 677
      pos 1410
      pos 1495
      pos 1537
      pos 1544
      pos 1727
      pos 2987
      pos 3123
      pos 3194
    doc 8
      freq 5
      pos 264
      pos 1751
      pos 2204
      pos 2340
      pos 2411
    doc 9
      freq 6
      pos 296
      pos 663
      pos 1575
      pos 1849
      pos 1985
      pos 2056
    doc 10
      freq 32
      pos 1555
      pos 2264
      pos 2499
      pos 2690
      pos 2746
      pos 3016
      pos 3284
      pos 3354
      pos 3666
      pos 3766
      pos 3875
      pos 4099
      pos 4223
      pos 5288
      pos 5444
      pos 8936
      pos 9973
      pos 9994
      pos 10210
      pos 10540
      pos 10983
      pos 11033
      pos 11123
      pos 11152
      pos 11395
      pos 11405
      pos 12203
      pos 12919
      pos 12940
      pos 13510
      pos 13646
      pos 13717
    doc 11
      freq 13
      pos 568
      pos 579
      pos 696
      pos 801
      pos 1745
      pos 2519
      pos 4427
      pos 7721
      pos 9185
      pos 9342
      pos 10671
      pos 10807
      pos 10878
    doc 12
      freq 34
      pos 94
      pos 658
      pos 849
      pos 953
      pos 1592
      pos 1895
      pos 2551
      pos 2559
      pos 2566
      pos 3228
      pos 3629
      pos 3889
      pos 3953
      pos 4034
      pos 4483
      pos 4493
      pos 4522
      pos 4770
      pos 4896
      pos 5025
      pos 5907
      pos 6113
      pos 6726
      pos 6869
      pos 6896
      pos 7518
      pos 7593
      pos 7638
      pos 7778
      pos 7802
      pos 9311
      pos 9521
      pos 9657
      pos 9728
    doc 13
      freq 36
      pos 94
      pos 191
      pos 400
      pos 468
      pos 988
      pos 1153
      pos 1161
      pos 1743
      pos 1785
      pos 2258
      pos 2575
      pos 2651
      pos 2663
      pos 2958
      pos 2980
      pos 3876
      pos 3898
      pos 3911
      pos 4190
      pos 4211
      pos 4327
      pos 4492
      pos 4552
      pos 4894
      pos 4937
      pos 5091
      pos 5260
      pos 5460
      pos 5710
      pos 5803
      pos 6642
      pos 6673
      pos 6984
      pos 7136
      pos 7272
      pos 7343
    doc 14
      freq 5
      pos 2148
      pos 5480
      pos 5602
      pos 5738
      pos 5809
    doc 15
      freq 23
      pos 168
      pos 172
      pos 498
      pos 505
      pos 895
      pos 1053
      pos 1177
      pos 1216
      pos 1274
      pos 1845
      pos 1985
      pos 1990
      pos 2176
      pos 2457
      pos 3113
      pos 3420
      pos 3472
      pos 3595
      pos 3636
      pos 3886
      pos 4121
      pos 4257
      pos 4328
    doc 16
      freq 8
      pos 107
      pos 127
      pos 194
      pos 211
      pos 869
      pos 2732
      pos 2868
      pos 2939
    doc 17
      freq 4
      pos 138
      pos 2456
      pos 2592
      pos 2663
    doc 18
      freq 24
      pos 29
      pos 122
      pos 349
      pos 353
      pos 374
      pos 451
      pos 459
      pos 501
      pos 522
      pos 533
      pos 597
      pos 1567
      pos 1592
      pos 1641
      pos 1653
      pos 1671
      pos 1699
      pos 1719
      pos 1728
      pos 1767
      pos 1798
      pos 2244
      pos 2380
      pos 2451
    skipList 
      level 0
        skipDoc 7
        skipDocFP 1645542
        impacts 
          impact 
            freq 16
            norm 100
          impact 
            freq 51
            norm 107
          impact 
            freq 83
            norm 120
        impactsEnd 
        skipDoc 15
        skipDocFP 1649659
        impacts 
          impact 
            freq 6
            norm 95
          impact 
            freq 23
            norm 104
          impact 
            freq 36
            norm 109
        impactsEnd 
  term onc
    doc 7
      freq 1
      pos 2746
  term once
    doc 1
      freq 3
      pos 2808
      pos 4909
      pos 5160
    doc 2
      freq 1
      pos 6257
    doc 10
      freq 3
      pos 1293
      pos 4102
      pos 4783
  term one
    doc 0
      freq 46
      pos 686
      pos 1299
      pos 1521
      pos 1539
      pos 1928
      pos 2289
      pos 2314
      pos 3058
      pos 3116
      pos 3147
      pos 3419
      pos 3602
      pos 3825
      pos 4110
      pos 4325
      pos 4492
      pos 4496
      pos 5378
      pos 5991
      pos 6043
      pos 6512
      pos 6681
      pos 7891
      pos 8287
      pos 8290
      pos 8293
      pos 8316
      pos 8319
      pos 8322
      pos 8805
      pos 8861
      pos 9459
      pos 9514
      pos 9539
      pos 9642
      pos 9724
      pos 9762
      pos 9867
      pos 9924
      pos 10597
      pos 10868
      pos 10953
      pos 11189
      pos 12839
      pos 13387
      pos 14020
    doc 1
      freq 20
      pos 528
      pos 862
      pos 1255
      pos 2161
      pos 2169
      pos 2215
      pos 3091
      pos 3371
      pos 3935
      pos 4173
      pos 4531
      pos 4787
      pos 4939
      pos 6325
      pos 7041
      pos 7055
      pos 7965
      pos 8769
      pos 8781
      pos 8809
    doc 2
      freq 5
      pos 408
      pos 432
      pos 1591
      pos 5236
      pos 6379
    doc 3
      freq 10
      pos 402
      pos 1124
      pos 1142
      pos 2251
      pos 2407
      pos 2640
      pos 2644
      pos 3545
      pos 3947
      pos 3955
    doc 4
      freq 7
      pos 913
      pos 1093
      pos 1119
      pos 1551
      pos 2491
      pos 2536
      pos 2914
    doc 5
      freq 13
      pos 221
      pos 465
      pos 700
      pos 977
      pos 1217
      pos 1233
      pos 1996
      pos 2085
      pos 2111
      pos 2156
      pos 3220
      pos 3415
      pos 3673
    doc 6
      freq 1
      pos 2288
    doc 7
      freq 6
      pos 581
      pos 1132
      pos 1175
      pos 1179
      pos 1402
      pos 1671
    doc 8
      freq 7
      pos 677
      pos 686
      pos 698
      pos 700
      pos 707
      pos 709
      pos 937
    doc 10
      freq 28
      pos 613
      pos 622
      pos 646
      pos 1172
      pos 1412
      pos 1451
      pos 2153
      pos 2254
      pos 2286
      pos 2742
      pos 2756
      pos 2859
      pos 2900
      pos 2930
      pos 3417
      pos 3866
      pos 4370
      pos 5058
      pos 5453
      pos 8427
      pos 9406
      pos 9505
      pos 10033
      pos 10796
      pos 11164
      pos 11309
      pos 11331
      pos 13057
    doc 11
      freq 3
      pos 1064
      pos 1173
      pos 2774
    doc 12
      freq 28
      pos 802
      pos 1119
      pos 1881
      pos 2043
      pos 2183
      pos 2261
      pos 2921
      pos 3180
      pos 3434
      pos 3521
      pos 3709
      pos 4748
      pos 5042
      pos 5284
      pos 5287
      pos 5303
      pos 5337
      pos 5779
      pos 5808
      pos 5864
      pos 5974
      pos 6017
      pos 6027
      pos 6177
      pos 6575
      pos 8841
      pos 8925
      pos 9293
    doc 13
      freq 13
      pos 1275
      pos 1352
      pos 1479
      pos 2052
      pos 3216
      pos 3846
      pos 4687
      pos 5153
      pos 5266
      pos 5665
      pos 5671
      pos 5676
      pos 6729
    doc 14
      freq 16
      pos 284
      pos 500
      pos 517
      pos 952
      pos 969
      pos 1046
      pos 1265
      pos 1306
      pos 1418
      pos 1595
      pos 1621
      pos 1698
      pos 2315
      pos 2811
      pos 2852
      pos 4165
    doc 15
      freq 14
      pos 581
      pos 989
      pos 1433
      pos 1480
      pos 1603
      pos 1644
      pos 1828
      pos 1867
      pos 2179
      pos 2292
      pos 2510
      pos 2518
      pos 3012
      pos 3516
    doc 16
      freq 6
      pos 520
      pos 573
      pos 1262
      pos 2277
      pos 2467
      pos 2581
    doc 17
      freq 13
      pos 87
      pos 144
      pos 360
      pos 478
      pos 695
      pos 954
      pos 967
      pos 1227
      pos 1304
      pos 1347
      pos 1905
      pos 1939
      pos 2103
    doc 18
      freq 1
      pos 1358
    skipList 
      level 0
        skipDoc 7
        skipDocFP 1653543
        impacts 
          impact 
            freq 6
            norm 100
          impact 
            freq 13
            norm 104
          impact 
            freq 20
            norm 113
          impact 
            freq 46
            norm 120
        impactsEnd 
        skipDoc 16
        skipDocFP 1655346
        impacts 
          impact 
            freq 7
            norm 97
          impact 
            freq 14
            norm 104
          impact 
            freq 16
            norm 107
          impact 
            freq 28
            norm 113
        impactsEnd 
  term one's
    doc 4
      freq 2
      pos 1262
      pos 1266
  term ones
    doc 4
      freq 1
      pos 4956
    doc 10
      freq 2
      pos 5992
      pos 11072
    doc 13
      freq 1
      pos 6565
    doc 18
      freq 2
      pos 1259
      pos 1869
  term ongoing
    doc 6
      freq 2
      pos 102
      pos 995
    doc 7
      freq 1
      pos 645
  term onlin
    doc 14
      freq 1
      pos 545
  term only
    doc 0
      freq 117
      pos 1726
      pos 2276
      pos 2294
      pos 2954
      pos 3286
      pos 3472
      pos 4589
      pos 4616
      pos 4869
      pos 5245
      pos 6138
      pos 6238
      pos 6507
      pos 6615
      pos 6725
      pos 7318
      pos 7391
      pos 7424
      pos 7449
      pos 7476
      pos 7506
      pos 7549
      pos 7576
      pos 7620
      pos 7659
      pos 7687
      pos 7720
      pos 7903
      pos 7934
      pos 7971
      pos 8012
      pos 8051
      pos 8092
      pos 8146
      pos 8183
      pos 8217
      pos 8445
      pos 8513
      pos 8571
      pos 8629
      pos 8686
      pos 8731
      pos 8773
      pos 8980
      pos 9011
      pos 9056
      pos 9101
      pos 9125
      pos 9151
      pos 9181
      pos 9255
      pos 9295
      pos 9325
      pos 9535
      pos 9717
      pos 9758
      pos 9920
      pos 10596
      pos 11676
      pos 11849
      pos 11869
      pos 11903
      pos 11927
      pos 11949
      pos 11968
      pos 12168
      pos 12200
      pos 12222
      pos 12241
      pos 12264
      pos 14779
      pos 14786
      pos 14827
      pos 14839
      pos 14851
      pos 14863
      pos 14875
      pos 14887
      pos 14899
      pos 14911
      pos 14935
      pos 14947
      pos 14959
      pos 14971
      pos 14983
      pos 14995
      pos 15007
      pos 15019
      pos 15031
      pos 15043
      pos 15067
      pos 15079
      pos 15091
      pos 15103
      pos 15115
      pos 15127
      pos 15139
      pos 15151
      pos 15163
      pos 15187
      pos 15199
      pos 15211
      pos 15223
      pos 15235
      pos 15247
      pos 15259
      pos 15271
      pos 15283
      pos 15295
      pos 15319
      pos 15331
      pos 15343
      pos 15355
      pos 15367
      pos 15379
      pos 15391
      pos 16864
    doc 1
      freq 17
      pos 963
      pos 1741
      pos 2160
      pos 3223
      pos 3951
      pos 4271
      pos 4303
      pos 4990
      pos 5189
      pos 5394
      pos 5420
      pos 5434
      pos 6182
      pos 7290
      pos 7304
      pos 7339
      pos 7656
    doc 2
      freq 7
      pos 1293
      pos 1589
      pos 1651
      pos 1657
      pos 3535
      pos 3813
      pos 6264
    doc 3
      freq 10
      pos 671
      pos 846
      pos 1507
      pos 2104
      pos 2606
      pos 2659
      pos 2684
      pos 2690
      pos 4104
      pos 5171
    doc 4
      freq 5
      pos 2325
      pos 2392
      pos 4517
      pos 4696
      pos 4975
    doc 5
      freq 4
      pos 751
      pos 931
      pos 1504
      pos 2484
    doc 6
      freq 2
      pos 281
      pos 2822
    doc 7
      freq 2
      pos 1607
      pos 1613
    doc 8
      freq 1
      pos 1682
    doc 9
      freq 4
      pos 320
      pos 503
      pos 1140
      pos 1221
    doc 10
      freq 17
      pos 981
      pos 1171
      pos 1495
      pos 3227
      pos 4782
      pos 5452
      pos 6094
      pos 8803
      pos 9298
      pos 9504
      pos 9727
      pos 10198
      pos 10840
      pos 10941
      pos 11351
      pos 11999
      pos 12083
    doc 11
      freq 6
      pos 630
      pos 1780
      pos 2178
      pos 4809
      pos 4832
      pos 6127
    doc 12
      freq 36
      pos 279
      pos 1104
      pos 1152
      pos 1169
      pos 1313
      pos 1641
      pos 1932
      pos 2037
      pos 2516
      pos 2686
      pos 3132
      pos 3193
      pos 3341
      pos 3373
      pos 3423
      pos 3689
      pos 3835
      pos 3879
      pos 4126
      pos 4154
      pos 4165
      pos 4178
      pos 4589
      pos 5935
      pos 6543
      pos 6883
      pos 6960
      pos 8153
      pos 8197
      pos 8216
      pos 8599
      pos 8825
      pos 9068
      pos 9136
      pos 9226
      pos 9356
    doc 13
      freq 6
      pos 877
      pos 2210
      pos 2253
      pos 2610
      pos 4614
      pos 5424
    doc 14
      freq 9
      pos 1089
      pos 1129
      pos 1254
      pos 1295
      pos 1417
      pos 1594
      pos 1727
      pos 2105
      pos 2810
    doc 15
      freq 22
      pos 326
      pos 568
      pos 571
      pos 812
      pos 953
      pos 988
      pos 1544
      pos 1810
      pos 2067
      pos 2657
      pos 2672
      pos 2688
      pos 2717
      pos 2965
      pos 3018
      pos 3028
      pos 3549
      pos 3563
      pos 3568
      pos 3572
      pos 3674
      pos 3754
    doc 16
      freq 4
      pos 462
      pos 851
      pos 883
      pos 1048
    doc 17
      freq 3
      pos 681
      pos 946
      pos 1863
    skipList 
      level 0
        skipDoc 7
        skipDocFP 1658594
        impacts 
          impact 
            freq 2
            norm 100
          impact 
            freq 4
            norm 104
          impact 
            freq 10
            norm 107
          impact 
            freq 17
            norm 113
          impact 
            freq 117
            norm 120
        impactsEnd 
        skipDoc 15
        skipDocFP 1661296
        impacts 
          impact 
            freq 4
            norm 95
          impact 
            freq 22
            norm 104
          impact 
            freq 36
            norm 113
        impactsEnd 
  term ono
    doc 11
      freq 1
      pos 9701
  term ontar
    doc 3
      freq 1
      pos 4878
  term onto
    doc 1
      freq 1
      pos 1520
    doc 4
      freq 2
      pos 2554
      pos 5657
    doc 16
      freq 1
      pos 143
  term onus
    doc 15
      freq 1
      pos 1900
  term oo
    doc 16
      freq 1
      pos 2360
  term oo.example.com
    doc 14
      freq 2
      pos 4544
      pos 4565
  term oooo.example.com
    doc 14
      freq 2
      pos 4201
      pos 4371
  term ooooooooo.ooooooooooooooooooooooooooooooooooooo
    doc 14
      freq 1
      pos 4481
  term oooooooooooo.oooooooooooooooooooooooooooooooooo
    doc 14
      freq 1
      pos 4460
  term oooooooooooooooo.oooooooooooooooooooooooooooooo
    doc 14
      freq 1
      pos 4177
  term ooooooooooooooooo.ooooooooooooooooooooooooooooo
    doc 14
      freq 2
      pos 4243
      pos 4264
  term oooooooooooooooooo
    doc 14
      freq 1
      pos 4457
  term oooooooooooooooooo.oooooooooooooooooooooooooooo
    doc 14
      freq 2
      pos 4541
      pos 4562
  term oooooooooooooooooooo.oooooooooooooooooooooooooo
    doc 14
      freq 2
      pos 4198
      pos 4368
  term ooooooooooooooooooooooooo.ooooooooooooooooooooo
    doc 14
      freq 1
      pos 4482
  term oooooooooooooooooooooooooooo.example.com
    doc 14
      freq 1
      pos 4461
  term ooooooooooooooooooooooooooooooo.ooooooooooooooo
    doc 14
      freq 1
      pos 4389
  term oooooooooooooooooooooooooooooooo.oooooooooooooo
    doc 14
      freq 1
      pos 4178
  term ooooooooooooooooooooooooooooooooo.ooooooooooooo
    doc 14
      freq 2
      pos 4244
      pos 4265
  term oooooooooooooooooooooooooooooooooo.oooooooooooo
    doc 14
      freq 2
      pos 4542
      pos 4563
  term oooooooooooooooooooooooooooooooooooo.oooooooooo
    doc 14
      freq 2
      pos 4199
      pos 4369
  term ooooooooooooooooooooooooooooooooooooooooo.example.com
    doc 14
      freq 1
      pos 4483
  term oooooooooooooooooooooooooooooooooooooooooo
    doc 14
      freq 2
      pos 4197
      pos 4367
  term oooooooooooooooooooooooooooooooooooooooooooo
    doc 14
      freq 2
      pos 4540
      pos 4561
  term oooooooooooooooooooooooooooooooooooooooooooo.oo
    doc 14
      freq 1
      pos 4458
  term oooooooooooooooooooooooooooooooooooooooooooooo
    doc 14
      freq 2
      pos 4176
      pos 4390
  term ooooooooooooooooooooooooooooooooooooooooooooooo
    doc 14
      freq 9
      pos 4200
      pos 4245
      pos 4266
      pos 4370
      pos 4387
      pos 4459
      pos 4480
      pos 4543
      pos 4564
  term oooooooooooooooooooooooooooooooooooooooooooooooo.example.com
    doc 14
      freq 1
      pos 4179
  term oooooooooooooop.ooooooooooooooooooooooooooooooo
    doc 14
      freq 1
      pos 4388
  term op
    doc 3
      freq 1
      pos 2809
  term opalk
    doc 0
      freq 1
      pos 15955
  term opaqu
    doc 11
      freq 1
      pos 8068
  term open
    doc 0
      freq 1
      pos 16923
    doc 5
      freq 1
      pos 643
    doc 7
      freq 1
      pos 365
    doc 13
      freq 1
      pos 6681
    doc 17
      freq 2
      pos 2014
      pos 2132
  term opening
    doc 12
      freq 1
      pos 9233
  term openssl
    doc 10
      freq 1
      pos 6202
  term operat
    doc 3
      freq 1
      pos 5328
    doc 13
      freq 1
      pos 5292
    doc 15
      freq 1
      pos 2264
  term operated
    doc 3
      freq 1
      pos 2371
    doc 7
      freq 1
      pos 332
    doc 10
      freq 1
      pos 10952
  term operates
    doc 3
      freq 1
      pos 1122
  term operating
    doc 3
      freq 4
      pos 2487
      pos 2542
      pos 2601
      pos 5219
    doc 4
      freq 1
      pos 4740
    doc 12
      freq 1
      pos 3302
    doc 15
      freq 2
      pos 510
      pos 1971
  term operation
    doc 0
      freq 5
      pos 384
      pos 2120
      pos 2146
      pos 2216
      pos 5557
    doc 1
      freq 1
      pos 1675
    doc 2
      freq 3
      pos 2421
      pos 2740
      pos 5012
    doc 3
      freq 2
      pos 2804
      pos 5047
    doc 5
      freq 1
      pos 1096
    doc 6
      freq 1
      pos 2499
    doc 7
      freq 1
      pos 2049
    doc 10
      freq 2
      pos 2072
      pos 9014
    doc 12
      freq 3
      pos 2112
      pos 3035
      pos 7061
    doc 13
      freq 6
      pos 1402
      pos 1405
      pos 3860
      pos 5977
      pos 5995
      pos 6405
    doc 15
      freq 4
      pos 379
      pos 429
      pos 834
      pos 3235
    doc 16
      freq 1
      pos 1305
    doc 17
      freq 1
      pos 2020
    skipList 
      level 0
        skipDoc 10
        skipDocFP 1667639
        impacts 
          impact 
            freq 1
            norm 100
          impact 
            freq 2
            norm 107
          impact 
            freq 3
            norm 108
          impact 
            freq 5
            norm 120
        impactsEnd 
  term operational
    doc 10
      freq 3
      pos 3125
      pos 10923
      pos 13265
    doc 12
      freq 10
      pos 21
      pos 68
      pos 512
      pos 2126
      pos 3141
      pos 4552
      pos 6840
      pos 7337
      pos 9292
      pos 9361
    doc 13
      freq 1
      pos 2136
    doc 15
      freq 1
      pos 3278
    doc 17
      freq 1
      pos 199
  term operationalizing
    doc 10
      freq 1
      pos 9775
  term operationally
    doc 12
      freq 1
      pos 5541
  term operations
    doc 0
      freq 2
      pos 16143
      pos 16159
    doc 2
      freq 3
      pos 1283
      pos 1671
      pos 3543
    doc 3
      freq 3
      pos 1094
      pos 2780
      pos 3307
    doc 7
      freq 4
      pos 708
      pos 1019
      pos 2032
      pos 2559
    doc 10
      freq 3
      pos 193
      pos 1776
      pos 4276
    doc 12
      freq 2
      pos 563
      pos 6845
    doc 13
      freq 13
      pos 248
      pos 1259
      pos 3628
      pos 3834
      pos 3854
      pos 4425
      pos 4851
      pos 5182
      pos 5749
      pos 6410
      pos 6533
      pos 6540
      pos 6645
  term operator
    doc 0
      freq 1
      pos 16826
    doc 1
      freq 1
      pos 4848
    doc 3
      freq 1
      pos 5839
    doc 9
      freq 1
      pos 654
  term operators
    doc 12
      freq 1
      pos 8680
    doc 13
      freq 1
      pos 2718
  term opportunistic
    doc 10
      freq 1
      pos 10248
  term opportunistically
    doc 10
      freq 1
      pos 4319
  term opportunity
    doc 4
      freq 1
      pos 4410
    doc 9
      freq 1
      pos 863
  term opposed
    doc 2
      freq 1
      pos 4975
  term opposit
    doc 1
      freq 1
      pos 4720
    doc 3
      freq 1
      pos 5305
  term ops.ietf.org
    doc 12
      freq 1
      pos 7650
  term opt
    doc 10
      freq 2
      pos 5791
      pos 5821
  term optical
    doc 1
      freq 3
      pos 156
      pos 593
      pos 9127
  term optimal
    doc 12
      freq 1
      pos 3564
    doc 13
      freq 1
      pos 5462
    doc 15
      freq 1
      pos 2853
  term optimisation
    doc 15
      freq 1
      pos 3020
  term optimising
    doc 15
      freq 2
      pos 269
      pos 2792
  term optimization
    doc 9
      freq 3
      pos 21
      pos 168
      pos 1754
    doc 12
      freq 2
      pos 3058
      pos 8989
  term optimizing
    doc 12
      freq 1
      pos 3829
  term optinel
    doc 6
      freq 1
      pos 3163
  term option
    doc 0
      freq 3
      pos 13987
      pos 13994
      pos 14011
    doc 1
      freq 3
      pos 8627
      pos 8671
      pos 8691
    doc 3
      freq 2
      pos 2981
      pos 3014
    doc 4
      freq 6
      pos 1709
      pos 1718
      pos 3329
      pos 4434
      pos 4556
      pos 5844
    doc 5
      freq 3
      pos 827
      pos 1167
      pos 2221
    doc 7
      freq 23
      pos 1380
      pos 1550
      pos 1586
      pos 1838
      pos 1847
      pos 1852
      pos 1859
      pos 1864
      pos 1870
      pos 1876
      pos 1883
      pos 1890
      pos 1896
      pos 1903
      pos 1915
      pos 1922
      pos 1931
      pos 1937
      pos 1943
      pos 1949
      pos 1956
      pos 2110
      pos 2508
    doc 9
      freq 2
      pos 969
      pos 1270
    doc 10
      freq 1
      pos 7560
    doc 12
      freq 5
      pos 3522
      pos 3990
      pos 3993
      pos 7733
      pos 7818
    doc 13
      freq 1
      pos 2549
    doc 15
      freq 12
      pos 247
      pos 1271
      pos 1522
      pos 1553
      pos 1558
      pos 1625
      pos 2491
      pos 2512
      pos 2806
      pos 2938
      pos 3220
      pos 3529
    doc 17
      freq 2
      pos 427
      pos 1243
    skipList 
      level 0
        skipDoc 10
        skipDocFP 1671233
        impacts 
          impact 
            freq 2
            norm 95
          impact 
            freq 23
            norm 100
        impactsEnd 
  term optional
    doc 0
      freq 2
      pos 969
      pos 14548
    doc 1
      freq 10
      pos 1174
      pos 2102
      pos 2840
      pos 3014
      pos 3041
      pos 5482
      pos 6213
      pos 6223
      pos 6245
      pos 7137
    doc 3
      freq 7
      pos 1249
      pos 1457
      pos 2020
      pos 3157
      pos 3525
      pos 3742
      pos 5065
    doc 4
      freq 1
      pos 458
    doc 5
      freq 2
      pos 1062
      pos 2053
    doc 8
      freq 2
      pos 322
      pos 1032
    doc 9
      freq 1
      pos 359
    doc 10
      freq 2
      pos 692
      pos 5922
    doc 13
      freq 2
      pos 1198
      pos 2318
    doc 16
      freq 4
      pos 560
      pos 564
      pos 591
      pos 700
    doc 17
      freq 5
      pos 282
      pos 804
      pos 1100
      pos 1910
      pos 2312
    doc 18
      freq 1
      pos 397
    skipList 
      level 0
        skipDoc 10
        skipDocFP 1672702
        impacts 
          impact 
            freq 1
            norm 95
          impact 
            freq 2
            norm 97
          impact 
            freq 7
            norm 107
          impact 
            freq 10
            norm 113
        impactsEnd 
  term optionally
    doc 3
      freq 1
      pos 5361
  term options
    doc 3
      freq 4
      pos 295
      pos 5017
      pos 5026
      pos 5108
    doc 4
      freq 1
      pos 4538
    doc 5
      freq 1
      pos 2000
    doc 7
      freq 4
      pos 1349
      pos 1359
      pos 1478
      pos 1630
    doc 8
      freq 2
      pos 1049
      pos 1088
    doc 10
      freq 1
      pos 11306
    doc 11
      freq 33
      pos 2616
      pos 2674
      pos 2698
      pos 3507
      pos 3532
      pos 3613
      pos 3637
      pos 5047
      pos 5717
      pos 5784
      pos 5819
      pos 6434
      pos 6471
      pos 6496
      pos 6596
      pos 6634
      pos 6673
      pos 6707
      pos 6763
      pos 7100
      pos 7131
      pos 7283
      pos 7377
      pos 7397
      pos 7418
      pos 7506
      pos 7528
      pos 7733
      pos 7761
      pos 8315
      pos 8342
      pos 8601
      pos 8619
    doc 12
      freq 1
      pos 7285
    doc 13
      freq 1
      pos 2283
    doc 15
      freq 11
      pos 414
      pos 934
      pos 1525
      pos 1575
      pos 1649
      pos 1823
      pos 2079
      pos 2357
      pos 2500
      pos 2508
      pos 3713
    doc 17
      freq 1
      pos 1222
    skipList 
      level 0
        skipDoc 12
        skipDocFP 1673970
        impacts 
          impact 
            freq 2
            norm 97
          impact 
            freq 4
            norm 100
          impact 
            freq 33
            norm 114
        impactsEnd 
  term or
    doc 0
      freq 86
      pos 236
      pos 598
      pos 633
      pos 649
      pos 850
      pos 875
      pos 1287
      pos 1310
      pos 1361
      pos 1422
      pos 1836
      pos 1865
      pos 1929
      pos 2192
      pos 2873
      pos 3280
      pos 3337
      pos 3385
      pos 3429
      pos 3627
      pos 3658
      pos 3873
      pos 4143
      pos 4174
      pos 4373
      pos 4599
      pos 4627
      pos 4687
      pos 4944
      pos 5101
      pos 5368
      pos 5885
      pos 5972
      pos 6065
      pos 8405
      pos 8479
      pos 8541
      pos 8598
      pos 9169
      pos 9955
      pos 9963
      pos 9989
      pos 10016
      pos 10394
      pos 10520
      pos 10877
      pos 10905
      pos 10910
      pos 10940
      pos 10984
      pos 11028
      pos 11127
      pos 11237
      pos 11546
      pos 12803
      pos 13960
      pos 13975
      pos 14109
      pos 14149
      pos 14217
      pos 16029
      pos 16037
      pos 16112
      pos 16121
      pos 16285
      pos 16359
      pos 16397
      pos 16564
      pos 16670
      pos 16692
      pos 16707
      pos 16876
      pos 17280
      pos 17299
      pos 17320
      pos 17326
      pos 17342
      pos 17349
      pos 17361
      pos 17370
      pos 17381
      pos 17440
      pos 17452
      pos 17463
      pos 17496
      pos 17499
    doc 1
      freq 60
      pos 698
      pos 933
      pos 1782
      pos 2100
      pos 2661
      pos 2714
      pos 3110
      pos 3170
      pos 3277
      pos 3291
      pos 3345
      pos 3466
      pos 3472
      pos 3584
      pos 3875
      pos 3894
      pos 3917
      pos 3919
      pos 4180
      pos 4287
      pos 4349
      pos 4489
      pos 4854
      pos 5284
      pos 5425
      pos 5452
      pos 5733
      pos 5790
      pos 6427
      pos 6618
      pos 6658
      pos 6683
      pos 6744
      pos 6972
      pos 6987
      pos 7024
      pos 7107
      pos 7315
      pos 7327
      pos 7343
      pos 7405
      pos 7620
      pos 8150
      pos 8460
      pos 8517
      pos 8525
      pos 9661
      pos 9680
      pos 9701
      pos 9707
      pos 9723
      pos 9730
      pos 9742
      pos 9751
      pos 9762
      pos 9821
      pos 9833
      pos 9844
      pos 9877
      pos 9880
    doc 2
      freq 30
      pos 409
      pos 433
      pos 469
      pos 932
      pos 964
      pos 972
      pos 1090
      pos 1101
      pos 1124
      pos 1401
      pos 1423
      pos 1523
      pos 3822
      pos 4101
      pos 5233
      pos 6239
      pos 6458
      pos 6477
      pos 6498
      pos 6504
      pos 6520
      pos 6527
      pos 6539
      pos 6548
      pos 6559
      pos 6618
      pos 6630
      pos 6641
      pos 6674
      pos 6677
    doc 3
      freq 57
      pos 996
      pos 1130
      pos 1174
      pos 1313
      pos 1411
      pos 1446
      pos 1472
      pos 1503
      pos 1525
      pos 1544
      pos 1578
      pos 1628
      pos 1639
      pos 1647
      pos 1662
      pos 1797
      pos 1875
      pos 2176
      pos 2253
      pos 2467
      pos 2716
      pos 2722
      pos 2744
      pos 2767
      pos 2810
      pos 2960
      pos 2995
      pos 3033
      pos 3111
      pos 3380
      pos 3404
      pos 3413
      pos 3456
      pos 3496
      pos 3540
      pos 3600
      pos 3920
      pos 3948
      pos 4228
      pos 5176
      pos 5346
      pos 5391
      pos 5550
      pos 6010
      pos 6029
      pos 6050
      pos 6056
      pos 6072
      pos 6079
      pos 6091
      pos 6100
      pos 6111
      pos 6170
      pos 6182
      pos 6193
      pos 6226
      pos 6229
    doc 4
      freq 38
      pos 544
      pos 869
      pos 935
      pos 1164
      pos 1619
      pos 1805
      pos 1912
      pos 2237
      pos 2483
      pos 2619
      pos 2945
      pos 2951
      pos 3126
      pos 3164
      pos 3393
      pos 3654
      pos 3912
      pos 4043
      pos 4191
      pos 4224
      pos 4333
      pos 4339
      pos 4678
      pos 5020
      pos 6165
      pos 6184
      pos 6205
      pos 6211
      pos 6227
      pos 6234
      pos 6246
      pos 6255
      pos 6266
      pos 6325
      pos 6337
      pos 6348
      pos 6381
      pos 6384
    doc 5
      freq 23
      pos 240
      pos 3154
      pos 3182
      pos 3323
      pos 3416
      pos 3449
      pos 3463
      pos 3798
      pos 4014
      pos 4495
      pos 4514
      pos 4535
      pos 4541
      pos 4557
      pos 4564
      pos 4576
      pos 4585
      pos 4596
      pos 4655
      pos 4667
      pos 4678
      pos 4711
      pos 4714
    doc 6
      freq 48
      pos 136
      pos 193
      pos 214
      pos 413
      pos 471
      pos 819
      pos 823
      pos 853
      pos 962
      pos 968
      pos 984
      pos 994
      pos 1021
      pos 1108
      pos 1208
      pos 1347
      pos 1541
      pos 1604
      pos 2049
      pos 2074
      pos 2209
      pos 2256
      pos 2310
      pos 2359
      pos 2422
      pos 2424
      pos 2439
      pos 2460
      pos 2484
      pos 2610
      pos 2736
      pos 2784
      pos 2802
      pos 2835
      pos 3295
      pos 3314
      pos 3335
      pos 3341
      pos 3357
      pos 3364
      pos 3376
      pos 3385
      pos 3396
      pos 3455
      pos 3467
      pos 3478
      pos 3511
      pos 3514
    doc 7
      freq 25
      pos 173
      pos 191
      pos 536
      pos 567
      pos 577
      pos 1196
      pos 1210
      pos 1223
      pos 1625
      pos 1672
      pos 1752
      pos 3000
      pos 3019
      pos 3040
      pos 3046
      pos 3062
      pos 3069
      pos 3081
      pos 3090
      pos 3101
      pos 3160
      pos 3172
      pos 3183
      pos 3216
      pos 3219
    doc 8
      freq 22
      pos 290
      pos 299
      pos 448
      pos 459
      pos 605
      pos 983
      pos 1277
      pos 1472
      pos 2217
      pos 2236
      pos 2257
      pos 2263
      pos 2279
      pos 2286
      pos 2298
      pos 2307
      pos 2318
      pos 2377
      pos 2389
      pos 2400
      pos 2433
      pos 2436
    doc 9
      freq 19
      pos 483
      pos 586
      pos 623
      pos 1312
      pos 1550
      pos 1862
      pos 1881
      pos 1902
      pos 1908
      pos 1924
      pos 1931
      pos 1943
      pos 1952
      pos 1963
      pos 2022
      pos 2034
      pos 2045
      pos 2078
      pos 2081
    doc 10
      freq 67
      pos 252
      pos 731
      pos 805
      pos 975
      pos 1016
      pos 1549
      pos 1610
      pos 1886
      pos 2122
      pos 2154
      pos 2383
      pos 2452
      pos 2528
      pos 2599
      pos 2708
      pos 2800
      pos 2823
      pos 2860
      pos 3254
      pos 3881
      pos 4130
      pos 4135
      pos 4140
      pos 4461
      pos 4714
      pos 4750
      pos 4755
      pos 4905
      pos 4917
      pos 4994
      pos 5538
      pos 6815
      pos 7494
      pos 7504
      pos 7645
      pos 8129
      pos 8705
      pos 9174
      pos 9242
      pos 9923
      pos 10149
      pos 10310
      pos 11216
      pos 11281
      pos 11336
      pos 11372
      pos 11403
      pos 11684
      pos 11778
      pos 12374
      pos 12870
      pos 12892
      pos 13040
      pos 13523
      pos 13542
      pos 13563
      pos 13569
      pos 13585
      pos 13592
      pos 13604
      pos 13613
      pos 13624
      pos 13683
      pos 13695
      pos 13706
      pos 13739
      pos 13742
    doc 11
      freq 28
      pos 703
      pos 914
      pos 1005
      pos 1798
      pos 2514
      pos 3607
      pos 4239
      pos 4643
      pos 7085
      pos 7177
      pos 7627
      pos 7715
      pos 8262
      pos 9791
      pos 10684
      pos 10703
      pos 10724
      pos 10730
      pos 10746
      pos 10753
      pos 10765
      pos 10774
      pos 10785
      pos 10844
      pos 10856
      pos 10867
      pos 10900
      pos 10903
    doc 12
      freq 81
      pos 360
      pos 384
      pos 575
      pos 795
      pos 815
      pos 975
      pos 1108
      pos 1156
      pos 1307
      pos 1541
      pos 1703
      pos 1840
      pos 2071
      pos 2123
      pos 2324
      pos 2460
      pos 2479
      pos 2757
      pos 2922
      pos 3430
      pos 3625
      pos 3919
      pos 4028
      pos 4052
      pos 4155
      pos 4373
      pos 4391
      pos 4435
      pos 4480
      pos 4488
      pos 4861
      pos 4986
      pos 5098
      pos 5185
      pos 5208
      pos 5260
      pos 5273
      pos 5309
      pos 5319
      pos 5376
      pos 5463
      pos 5775
      pos 5784
      pos 5913
      pos 6075
      pos 6425
      pos 6651
      pos 6914
      pos 7685
      pos 7961
      pos 8157
      pos 8192
      pos 8211
      pos 8281
      pos 8557
      pos 8583
      pos 8704
      pos 8743
      pos 8842
      pos 8850
      pos 8870
      pos 9176
      pos 9232
      pos 9267
      pos 9306
      pos 9396
      pos 9404
      pos 9534
      pos 9553
      pos 9574
      pos 9580
      pos 9596
      pos 9603
      pos 9615
      pos 9624
      pos 9635
      pos 9694
      pos 9706
      pos 9717
      pos 9750
      pos 9753
    doc 13
      freq 79
      pos 459
      pos 482
      pos 608
      pos 784
      pos 826
      pos 1276
      pos 1353
      pos 1391
      pos 1480
      pos 1773
      pos 1974
      pos 2088
      pos 2298
      pos 2485
      pos 2863
      pos 2952
      pos 2977
      pos 3003
      pos 3018
      pos 3046
      pos 3071
      pos 3096
      pos 3139
      pos 3201
      pos 3265
      pos 3284
      pos 3326
      pos 3378
      pos 3519
      pos 3556
      pos 3563
      pos 3612
      pos 3845
      pos 4041
      pos 4123
      pos 4287
      pos 4601
      pos 4764
      pos 4827
      pos 4841
      pos 4922
      pos 5004
      pos 5154
      pos 5161
      pos 5267
      pos 5324
      pos 5666
      pos 5672
      pos 5677
      pos 5690
      pos 5849
      pos 5889
      pos 5904
      pos 5999
      pos 6070
      pos 6093
      pos 6102
      pos 6367
      pos 6380
      pos 6478
      pos 6499
      pos 6508
      pos 6556
      pos 6629
      pos 6680
      pos 7149
      pos 7168
      pos 7189
      pos 7195
      pos 7211
      pos 7218
      pos 7230
      pos 7239
      pos 7250
      pos 7309
      pos 7321
      pos 7332
      pos 7365
      pos 7368
    doc 14
      freq 49
      pos 392
      pos 441
      pos 462
      pos 916
      pos 970
      pos 1395
      pos 1572
      pos 1622
      pos 1773
      pos 1812
      pos 2084
      pos 2142
      pos 2219
      pos 2284
      pos 2324
      pos 2697
      pos 2853
      pos 3204
      pos 3523
      pos 3810
      pos 4117
      pos 4180
      pos 4202
      pos 4247
      pos 4268
      pos 4372
      pos 4392
      pos 4462
      pos 4484
      pos 4545
      pos 4566
      pos 4857
      pos 4949
      pos 5120
      pos 5264
      pos 5615
      pos 5634
      pos 5655
      pos 5661
      pos 5677
      pos 5684
      pos 5696
      pos 5705
      pos 5716
      pos 5775
      pos 5787
      pos 5798
      pos 5831
      pos 5834
    doc 15
      freq 60
      pos 83
      pos 95
      pos 371
      pos 418
      pos 554
      pos 569
      pos 587
      pos 668
      pos 678
      pos 687
      pos 753
      pos 759
      pos 802
      pos 891
      pos 912
      pos 918
      pos 992
      pos 1122
      pos 1229
      pos 1466
      pos 1485
      pos 1511
      pos 1796
      pos 1840
      pos 1895
      pos 1938
      pos 1950
      pos 1996
      pos 2044
      pos 2061
      pos 2188
      pos 2201
      pos 2245
      pos 2376
      pos 2557
      pos 2699
      pos 2836
      pos 3060
      pos 3214
      pos 3294
      pos 3317
      pos 3363
      pos 3476
      pos 3566
      pos 3570
      pos 3761
      pos 4134
      pos 4153
      pos 4174
      pos 4180
      pos 4196
      pos 4203
      pos 4215
      pos 4224
      pos 4235
      pos 4294
      pos 4306
      pos 4317
      pos 4350
      pos 4353
    doc 16
      freq 38
      pos 123
      pos 204
      pos 490
      pos 572
      pos 574
      pos 584
      pos 586
      pos 611
      pos 614
      pos 617
      pos 625
      pos 866
      pos 887
      pos 896
      pos 989
      pos 1009
      pos 1020
      pos 1081
      pos 1105
      pos 1281
      pos 1373
      pos 1617
      pos 1650
      pos 1702
      pos 2745
      pos 2764
      pos 2785
      pos 2791
      pos 2807
      pos 2814
      pos 2826
      pos 2835
      pos 2846
      pos 2905
      pos 2917
      pos 2928
      pos 2961
      pos 2964
    doc 17
      freq 24
      pos 145
      pos 321
      pos 400
      pos 434
      pos 662
      pos 724
      pos 1425
      pos 1514
      pos 1627
      pos 1664
      pos 2469
      pos 2488
      pos 2509
      pos 2515
      pos 2531
      pos 2538
      pos 2550
      pos 2559
      pos 2570
      pos 2629
      pos 2641
      pos 2652
      pos 2685
      pos 2688
    doc 18
      freq 20
      pos 855
      pos 961
      pos 1065
      pos 1074
      pos 1090
      pos 1630
      pos 2257
      pos 2276
      pos 2297
      pos 2303
      pos 2319
      pos 2326
      pos 2338
      pos 2347
      pos 2358
      pos 2417
      pos 2429
      pos 2440
      pos 2473
      pos 2476
    skipList 
      level 0
        skipDoc 7
        skipDocFP 1675423
        impacts 
          impact 
            freq 25
            norm 100
          impact 
            freq 48
            norm 101
          impact 
            freq 57
            norm 107
          impact 
            freq 60
            norm 113
          impact 
            freq 86
            norm 120
        impactsEnd 
        skipDoc 15
        skipDocFP 1681128
        impacts 
          impact 
            freq 19
            norm 95
          impact 
            freq 22
            norm 97
          impact 
            freq 60
            norm 104
          impact 
            freq 79
            norm 109
          impact 
            freq 81
            norm 113
        impactsEnd 
  term order
    doc 0
      freq 2
      pos 10559
      pos 11615
    doc 1
      freq 3
      pos 3880
      pos 4322
      pos 6306
    doc 2
      freq 10
      pos 97
      pos 336
      pos 541
      pos 811
      pos 982
      pos 1217
      pos 4897
      pos 5169
      pos 5574
      pos 6021
    doc 3
      freq 7
      pos 479
      pos 501
      pos 1650
      pos 3037
      pos 3049
      pos 3450
      pos 5539
    doc 4
      freq 4
      pos 707
      pos 1721
      pos 1823
      pos 5507
    doc 5
      freq 8
      pos 505
      pos 2183
      pos 2770
      pos 2836
      pos 2876
      pos 3300
      pos 3328
      pos 3486
    doc 6
      freq 3
      pos 2052
      pos 2130
      pos 2151
    doc 9
      freq 2
      pos 1124
      pos 1564
    doc 10
      freq 14
      pos 1060
      pos 2329
      pos 2547
      pos 3233
      pos 3898
      pos 3922
      pos 3960
      pos 4335
      pos 4897
      pos 5028
      pos 10673
      pos 11585
      pos 12965
      pos 12994
    doc 13
      freq 3
      pos 1040
      pos 1995
      pos 6286
    doc 14
      freq 7
      pos 334
      pos 386
      pos 1101
      pos 1916
      pos 3872
      pos 4602
      pos 5050
    doc 15
      freq 4
      pos 1004
      pos 2000
      pos 2468
      pos 2950
    skipList 
      level 0
        skipDoc 9
        skipDocFP 1689466
        impacts 
          impact 
            freq 2
            norm 95
          impact 
            freq 3
            norm 101
          impact 
            freq 8
            norm 104
          impact 
            freq 10
            norm 108
        impactsEnd 
  term ordered
    doc 0
      freq 1
      pos 3208
    doc 3
      freq 1
      pos 3731
    doc 14
      freq 1
      pos 78
    doc 15
      freq 2
      pos 1298
      pos 2190
  term ordering
    doc 0
      freq 1
      pos 1475
    doc 3
      freq 7
      pos 240
      pos 2909
      pos 2921
      pos 2964
      pos 2978
      pos 3005
      pos 3472
    doc 11
      freq 1
      pos 1309
    doc 18
      freq 2
      pos 670
      pos 1214
  term org
    doc 2
      freq 3
      pos 2764
      pos 2787
      pos 2892
  term organisation
    doc 15
      freq 1
      pos 1121
  term organiz
    doc 12
      freq 1
      pos 6661
  term organization
    doc 0
      freq 2
      pos 1079
      pos 17276
    doc 1
      freq 1
      pos 9657
    doc 2
      freq 1
      pos 6454
    doc 3
      freq 1
      pos 6006
    doc 4
      freq 1
      pos 6161
    doc 5
      freq 1
      pos 4491
    doc 6
      freq 1
      pos 3291
    doc 7
      freq 1
      pos 2996
    doc 8
      freq 1
      pos 2213
    doc 9
      freq 1
      pos 1858
    doc 10
      freq 1
      pos 13519
    doc 11
      freq 1
      pos 10680
    doc 12
      freq 2
      pos 6204
      pos 9530
    doc 13
      freq 1
      pos 7145
    doc 14
      freq 1
      pos 5611
    doc 15
      freq 1
      pos 4130
    doc 16
      freq 1
      pos 2741
    doc 17
      freq 10
      pos 529
      pos 576
      pos 866
      pos 891
      pos 1116
      pos 1128
      pos 2173
      pos 2213
      pos 2238
      pos 2465
    doc 18
      freq 1
      pos 2253
    skipList 
      level 0
        skipDoc 7
        skipDocFP 1691755
        impacts 
          impact 
            freq 1
            norm 100
          impact 
            freq 2
            norm 120
        impactsEnd 
        skipDoc 15
        skipDocFP 1692075
        impacts 
          impact 
            freq 1
            norm 95
          impact 
            freq 2
            norm 113
        impactsEnd 
  term organization's
    doc 13
      freq 1
      pos 536
    doc 17
      freq 1
      pos 1135
  term organizations
    doc 2
      freq 2
      pos 103
      pos 465
  term organized
    doc 2
      freq 2
      pos 403
      pos 1773
    doc 11
      freq 1
      pos 624
  term orientated
    doc 13
      freq 2
      pos 198
      pos 2730
  term oriented
    doc 1
      freq 2
      pos 578
      pos 587
  term origin
    doc 0
      freq 1
      pos 11681
    doc 2
      freq 1
      pos 5371
    doc 5
      freq 3
      pos 408
      pos 438
      pos 459
  term original
    doc 0
      freq 1
      pos 2187
    doc 1
      freq 1
      pos 692
    doc 2
      freq 2
      pos 3524
      pos 4231
    doc 3
      freq 1
      pos 478
    doc 4
      freq 5
      pos 1498
      pos 1583
      pos 1613
      pos 3462
      pos 3503
    doc 10
      freq 10
      pos 379
      pos 3413
      pos 3434
      pos 3461
      pos 8767
      pos 10621
      pos 10661
      pos 12221
      pos 12284
      pos 12839
    doc 15
      freq 3
      pos 107
      pos 314
      pos 541
    doc 16
      freq 5
      pos 470
      pos 501
      pos 689
      pos 1175
      pos 1711
    skipList 
      level 0
        skipDoc 16
        skipDocFP 1693661
        impacts 
          impact 
            freq 5
            norm 99
          impact 
            freq 10
            norm 116
        impactsEnd 
  term originally
    doc 2
      freq 2
      pos 3978
      pos 4626
  term originat
    doc 0
      freq 1
      pos 4947
    doc 4
      freq 7
      pos 2562
      pos 2922
      pos 3143
      pos 3411
      pos 3992
      pos 4832
      pos 5922
    doc 10
      freq 1
      pos 113
  term originated
    doc 0
      freq 3
      pos 1457
      pos 3543
      pos 4771
    doc 4
      freq 4
      pos 1213
      pos 1399
      pos 1638
      pos 3975
    doc 10
      freq 1
      pos 9111
  term originates
    doc 4
      freq 4
      pos 1065
      pos 1849
      pos 3675
      pos 3841
  term originating
    doc 0
      freq 1
      pos 1518
    doc 1
      freq 1
      pos 8281
    doc 4
      freq 6
      pos 1833
      pos 2053
      pos 2244
      pos 2904
      pos 3689
      pos 3855
  term originatingl1lspbuffersiz
    doc 0
      freq 1
      pos 4799
  term originatinglspbuffersiz
    doc 0
      freq 1
      pos 12552
  term originator
    doc 4
      freq 6
      pos 1033
      pos 1813
      pos 2220
      pos 2840
      pos 3107
      pos 4157
    doc 10
      freq 3
      pos 576
      pos 1389
      pos 1968
    doc 13
      freq 4
      pos 5807
      pos 5822
      pos 5839
      pos 5973
  term originator's
    doc 4
      freq 1
      pos 4207
  term originators
    doc 10
      freq 1
      pos 129
  term orkfysjjbzjwslmktrgtt
    doc 10
      freq 1
      pos 6216
  term orton
    doc 11
      freq 1
      pos 9583
  term orxsspqctp4h
    doc 11
      freq 1
      pos 10353
  term osi
    doc 0
      freq 3
      pos 1415
      pos 16935
      pos 16965
    doc 7
      freq 6
      pos 258
      pos 788
      pos 1972
      pos 2052
      pos 2115
      pos 2193
    doc 17
      freq 1
      pos 2022
  term osinlcp
    doc 7
      freq 1
      pos 2120
  term ospf
    doc 7
      freq 4
      pos 750
      pos 2103
      pos 2523
      pos 2698
  term ospfv2
    doc 0
      freq 1
      pos 11657
  term ospfv3
    doc 0
      freq 1
      pos 11659
  term ostensibly
    doc 11
      freq 2
      pos 3219
      pos 4375
  term osterhout
    doc 11
      freq 1
      pos 9585
  term other
    doc 0
      freq 10
      pos 1472
      pos 3388
      pos 6699
      pos 7596
      pos 8943
      pos 11671
      pos 13063
      pos 16538
      pos 17350
      pos 17500
    doc 1
      freq 20
      pos 720
      pos 869
      pos 935
      pos 1784
      pos 1933
      pos 1951
      pos 1964
      pos 3102
      pos 3851
      pos 3943
      pos 3997
      pos 4801
      pos 5207
      pos 6008
      pos 7051
      pos 7972
      pos 8152
      pos 8203
      pos 9731
      pos 9881
    doc 2
      freq 6
      pos 464
      pos 702
      pos 4050
      pos 5242
      pos 6528
      pos 6678
    doc 3
      freq 8
      pos 961
      pos 1977
      pos 5113
      pos 5126
      pos 5245
      pos 5271
      pos 6080
      pos 6230
    doc 4
      freq 12
      pos 357
      pos 361
      pos 492
      pos 1149
      pos 1211
      pos 2261
      pos 2456
      pos 2534
      pos 2928
      pos 4706
      pos 6235
      pos 6385
    doc 5
      freq 5
      pos 650
      pos 1895
      pos 2166
      pos 4565
      pos 4715
    doc 6
      freq 8
      pos 215
      pos 333
      pos 581
      pos 751
      pos 855
      pos 1026
      pos 3365
      pos 3515
    doc 7
      freq 2
      pos 3070
      pos 3220
    doc 8
      freq 3
      pos 75
      pos 2287
      pos 2437
    doc 9
      freq 7
      pos 298
      pos 373
      pos 585
      pos 1107
      pos 1411
      pos 1932
      pos 2082
    doc 10
      freq 16
      pos 540
      pos 1116
      pos 1136
      pos 1196
      pos 1206
      pos 1309
      pos 1891
      pos 5735
      pos 6142
      pos 7864
      pos 9741
      pos 10227
      pos 10615
      pos 11407
      pos 13593
      pos 13743
    doc 11
      freq 10
      pos 1234
      pos 3608
      pos 3926
      pos 4857
      pos 7071
      pos 7599
      pos 7826
      pos 7931
      pos 10754
      pos 10904
    doc 12
      freq 15
      pos 206
      pos 628
      pos 851
      pos 1500
      pos 3370
      pos 5109
      pos 5848
      pos 5904
      pos 6115
      pos 6354
      pos 6898
      pos 6972
      pos 8947
      pos 9604
      pos 9754
    doc 13
      freq 13
      pos 390
      pos 516
      pos 636
      pos 1264
      pos 2346
      pos 2623
      pos 2891
      pos 5948
      pos 5956
      pos 6150
      pos 6515
      pos 7219
      pos 7369
    doc 14
      freq 5
      pos 110
      pos 424
      pos 2061
      pos 5685
      pos 5835
    doc 15
      freq 13
      pos 280
      pos 411
      pos 739
      pos 1038
      pos 1611
      pos 2018
      pos 2238
      pos 2452
      pos 3053
      pos 3129
      pos 3364
      pos 4204
      pos 4354
    doc 16
      freq 4
      pos 493
      pos 1016
      pos 2815
      pos 2965
    doc 17
      freq 5
      pos 198
      pos 1810
      pos 1877
      pos 2539
      pos 2689
    doc 18
      freq 3
      pos 813
      pos 2327
      pos 2477
    skipList 
      level 0
        skipDoc 7
        skipDocFP 1696643
        impacts 
          impact 
            freq 2
            norm 100
          impact 
            freq 8
            norm 101
          impact 
            freq 12
            norm 108
          impact 
            freq 20
            norm 113
        impactsEnd 
        skipDoc 15
        skipDocFP 1697885
        impacts 
          impact 
            freq 7
            norm 95
          impact 
            freq 13
            norm 104
          impact 
            freq 15
            norm 113
          impact 
            freq 16
            norm 116
        impactsEnd 
  term otherconfig
    doc 15
      freq 1
      pos 781
  term others
    doc 0
      freq 1
      pos 2440
    doc 5
      freq 1
      pos 707
    doc 11
      freq 2
      pos 635
      pos 9608
    doc 12
      freq 1
      pos 2088
    doc 13
      freq 2
      pos 910
      pos 6588
    doc 14
      freq 1
      pos 5290
  term otherwis
    doc 0
      freq 5
      pos 8485
      pos 8547
      pos 8604
      pos 16398
      pos 16440
    doc 1
      freq 1
      pos 4743
    doc 2
      freq 1
      pos 2104
    doc 5
      freq 1
      pos 2070
    doc 10
      freq 1
      pos 11692
    doc 11
      freq 2
      pos 1868
      pos 6109
    doc 12
      freq 5
      pos 1530
      pos 4724
      pos 8572
      pos 8908
      pos 9405
    doc 13
      freq 1
      pos 5005
    doc 14
      freq 8
      pos 641
      pos 737
      pos 768
      pos 942
      pos 992
      pos 1428
      pos 1459
      pos 1644
    doc 17
      freq 1
      pos 1250
    doc 18
      freq 1
      pos 135
    skipList 
      level 0
        skipDoc 13
        skipDocFP 1700554
        impacts 
          impact 
            freq 1
            norm 104
          impact 
            freq 5
            norm 113
        impactsEnd 
  term ott
    doc 13
      freq 3
      pos 20
      pos 6813
      pos 7040
  term otto
    doc 5
      freq 2
      pos 4401
      pos 4415
  term our
    doc 0
      freq 6
      pos 688
      pos 5157
      pos 5186
      pos 13293
      pos 13354
      pos 14024
    doc 7
      freq 2
      pos 469
      pos 1239
    doc 16
      freq 2
      pos 2013
      pos 2044
  term ours
    doc 0
      freq 1
      pos 13061
  term out
    doc 0
      freq 3
      pos 4992
      pos 5098
      pos 5132
    doc 1
      freq 1
      pos 1151
    doc 2
      freq 1
      pos 1443
    doc 3
      freq 9
      pos 713
      pos 806
      pos 1648
      pos 3035
      pos 3047
      pos 3448
      pos 4138
      pos 5573
      pos 5860
    doc 4
      freq 3
      pos 1878
      pos 4636
      pos 5933
    doc 5
      freq 3
      pos 189
      pos 2200
      pos 2496
    doc 6
      freq 4
      pos 2050
      pos 2128
      pos 2149
      pos 2809
    doc 7
      freq 1
      pos 1604
    doc 11
      freq 1
      pos 657
    doc 12
      freq 3
      pos 1875
      pos 4328
      pos 5129
    doc 13
      freq 2
      pos 2419
      pos 5030
    doc 15
      freq 1
      pos 1683
    doc 17
      freq 1
      pos 1921
    skipList 
      level 0
        skipDoc 7
        skipDocFP 1701879
        impacts 
          impact 
            freq 1
            norm 100
          impact 
            freq 4
            norm 101
          impact 
            freq 9
            norm 107
        impactsEnd 
  term outages
    doc 0
      freq 2
      pos 16228
      pos 16381
  term outbound
    doc 10
      freq 1
      pos 4547
  term outdated
    doc 10
      freq 1
      pos 8502
    doc 13
      freq 1
      pos 6518
  term outermost
    doc 3
      freq 1
      pos 2662
  term outgoing
    doc 1
      freq 4
      pos 1597
      pos 1629
      pos 1655
      pos 2868
    doc 4
      freq 1
      pos 2886
  term outlined
    doc 1
      freq 1
      pos 4864
    doc 5
      freq 2
      pos 3771
      pos 3978
    doc 9
      freq 1
      pos 1049
  term outlining
    doc 2
      freq 1
      pos 1419
  term output
    doc 1
      freq 2
      pos 7402
      pos 7426
    doc 3
      freq 1
      pos 2048
    doc 5
      freq 6
      pos 1275
      pos 1316
      pos 1342
      pos 1369
      pos 1925
      pos 1940
    doc 7
      freq 4
      pos 129
      pos 463
      pos 1869
      pos 1893
    doc 10
      freq 1
      pos 12367
    doc 11
      freq 1
      pos 9784
    doc 14
      freq 1
      pos 2116
    doc 16
      freq 2
      pos 280
      pos 685
    skipList 
      level 0
        skipDoc 16
        skipDocFP 1703582
        impacts 
          impact 
            freq 2
            norm 99
          impact 
            freq 4
            norm 100
          impact 
            freq 6
            norm 104
        impactsEnd 
  term outs
    doc 12
      freq 3
      pos 1805
      pos 3640
      pos 3806
  term outsid
    doc 1
      freq 4
      pos 954
      pos 2044
      pos 3316
      pos 8080
    doc 2
      freq 2
      pos 1701
      pos 1967
    doc 3
      freq 4
      pos 1075
      pos 1495
      pos 1536
      pos 3135
    doc 4
      freq 1
      pos 4971
    doc 10
      freq 6
      pos 3668
      pos 3849
      pos 7498
      pos 8140
      pos 9779
      pos 11416
    doc 11
      freq 2
      pos 4753
      pos 4961
    doc 13
      freq 1
      pos 3347
    doc 16
      freq 2
      pos 411
      pos 1030
    skipList 
      level 0
        skipDoc 16
        skipDocFP 1704415
        impacts 
          impact 
            freq 2
            norm 99
          impact 
            freq 4
            norm 107
          impact 
            freq 6
            norm 116
        impactsEnd 
  term outsiders
    doc 12
      freq 1
      pos 7976
  term outstanding
    doc 2
      freq 1
      pos 4833
  term over
    doc 0
      freq 3
      pos 10485
      pos 11515
      pos 11579
    doc 1
      freq 16
      pos 121
      pos 137
      pos 160
      pos 457
      pos 575
      pos 635
      pos 666
      pos 1413
      pos 1429
      pos 1991
      pos 8990
      pos 9007
      pos 9042
      pos 9065
      pos 9089
      pos 9114
    doc 2
      freq 1
      pos 5000
    doc 3
      freq 38
      pos 36
      pos 114
      pos 127
      pos 172
      pos 337
      pos 358
      pos 377
      pos 584
      pos 764
      pos 1043
      pos 1429
      pos 1782
      pos 2121
      pos 2279
      pos 2432
      pos 2497
      pos 2827
      pos 2914
      pos 3211
      pos 3330
      pos 3393
      pos 3587
      pos 3620
      pos 3875
      pos 4014
      pos 4302
      pos 4328
      pos 4563
      pos 4744
      pos 4837
      pos 4941
      pos 5006
      pos 5202
      pos 5440
      pos 5544
      pos 5592
      pos 5793
      pos 5949
    doc 4
      freq 1
      pos 2045
    doc 6
      freq 12
      pos 212
      pos 304
      pos 321
      pos 570
      pos 1023
      pos 1077
      pos 1323
      pos 1523
      pos 2055
      pos 2365
      pos 2722
      pos 2915
    doc 7
      freq 14
      pos 787
      pos 792
      pos 860
      pos 867
      pos 1008
      pos 2050
      pos 2192
      pos 2197
      pos 2202
      pos 2270
      pos 2277
      pos 2495
      pos 2544
      pos 2668
    doc 8
      freq 15
      pos 670
      pos 732
      pos 739
      pos 747
      pos 754
      pos 762
      pos 1880
      pos 1897
      pos 1917
      pos 1954
      pos 1978
      pos 2002
      pos 2028
      pos 2047
      pos 2119
    doc 9
      freq 3
      pos 1386
      pos 1427
      pos 1594
    doc 10
      freq 20
      pos 1840
      pos 1909
      pos 2641
      pos 3003
      pos 3616
      pos 6458
      pos 7208
      pos 7404
      pos 8223
      pos 8241
      pos 8827
      pos 8845
      pos 8893
      pos 9074
      pos 9125
      pos 9613
      pos 9631
      pos 10061
      pos 10188
      pos 13278
    doc 11
      freq 8
      pos 1215
      pos 3221
      pos 4370
      pos 4392
      pos 4550
      pos 4568
      pos 8280
      pos 8298
    doc 12
      freq 8
      pos 927
      pos 932
      pos 3601
      pos 4108
      pos 4937
      pos 7613
      pos 8741
      pos 8753
    doc 13
      freq 11
      pos 543
      pos 2027
      pos 2366
      pos 2499
      pos 2518
      pos 2701
      pos 2714
      pos 4239
      pos 5138
      pos 5151
      pos 6511
    doc 15
      freq 6
      pos 1278
      pos 2374
      pos 2401
      pos 3551
      pos 3627
      pos 3676
    doc 16
      freq 2
      pos 461
      pos 1382
    skipList 
      level 0
        skipDoc 8
        skipDocFP 1705340
        impacts 
          impact 
            freq 15
            norm 97
          impact 
            freq 38
            norm 107
        impactsEnd 
  term overall
    doc 2
      freq 1
      pos 5591
  term overcom
    doc 2
      freq 1
      pos 4811
    doc 6
      freq 1
      pos 2909
    doc 13
      freq 1
      pos 1956
  term overell
    doc 10
      freq 1
      pos 13189
    doc 16
      freq 1
      pos 2610
  term overflow
    doc 6
      freq 2
      pos 412
      pos 2421
  term overhead
    doc 1
      freq 1
      pos 6157
    doc 2
      freq 1
      pos 1315
    doc 5
      freq 1
      pos 111
    doc 14
      freq 1
      pos 2692
  term overlap
    doc 15
      freq 1
      pos 3726
  term overlarg
    doc 11
      freq 6
      pos 271
      pos 279
      pos 381
      pos 4743
      pos 4951
      pos 6939
  term overload
    doc 0
      freq 9
      pos 4951
      pos 4975
      pos 4981
      pos 5028
      pos 5056
      pos 5076
      pos 5089
      pos 5119
      pos 12806
  term overloaded
    doc 0
      freq 5
      pos 1653
      pos 4909
      pos 4933
      pos 4945
      pos 7461
  term overnight
    doc 10
      freq 1
      pos 11180
  term overrides
    doc 9
      freq 1
      pos 1251
  term oversubscription
    doc 6
      freq 1
      pos 2504
  term overtur
    doc 11
      freq 1
      pos 5056
  term overview
    doc 0
      freq 3
      pos 149
      pos 201
      pos 300
    doc 5
      freq 2
      pos 266
      pos 1079
    doc 6
      freq 2
      pos 913
      pos 2981
    doc 10
      freq 3
      pos 191
      pos 1774
      pos 1786
    doc 11
      freq 2
      pos 99
      pos 559
    doc 12
      freq 1
      pos 586
  term overwrit
    doc 15
      freq 1
      pos 1096
  term overwriting
    doc 3
      freq 1
      pos 995
  term ovgtw0lu5csip
    doc 10
      freq 2
      pos 7281
      pos 7371
  term ovzvw3an
    doc 10
      freq 1
      pos 12716
  term own
    doc 0
      freq 1
      pos 7590
    doc 2
      freq 2
      pos 1398
      pos 1632
    doc 3
      freq 1
      pos 5386
    doc 4
      freq 1
      pos 2541
    doc 8
      freq 1
      pos 1704
    doc 10
      freq 3
      pos 1638
      pos 8751
      pos 8865
    doc 12
      freq 1
      pos 4271
    doc 16
      freq 1
      pos 378
    doc 17
      freq 1
      pos 1190
    skipList 
      level 0
        skipDoc 16
        skipDocFP 1710073
        impacts 
          impact 
            freq 1
            norm 97
          impact 
            freq 2
            norm 108
          impact 
            freq 3
            norm 116
        impactsEnd 
  term owner
    doc 12
      freq 1
      pos 5639
    doc 14
      freq 31
      pos 111
      pos 331
      pos 367
      pos 493
      pos 505
      pos 514
      pos 704
      pos 1080
      pos 1108
      pos 1133
      pos 1137
      pos 1205
      pos 1259
      pos 1300
      pos 1401
      pos 1423
      pos 1474
      pos 1578
      pos 1600
      pos 1754
      pos 1778
      pos 1828
      pos 2073
      pos 2321
      pos 2531
      pos 2845
      pos 2891
      pos 3854
      pos 4611
      pos 5032
      pos 5179
    doc 18
      freq 11
      pos 210
      pos 234
      pos 426
      pos 656
      pos 696
      pos 725
      pos 769
      pos 1088
      pos 1104
      pos 1623
      pos 1628
  term ownernames
    doc 14
      freq 1
      pos 2607
  term owners
    doc 18
      freq 1
      pos 279
  term ownlsppurges
    doc 0
      freq 1
      pos 7600
  term ox4
    doc 14
      freq 1
      pos 5516
  term oxford
    doc 14
      freq 1
      pos 5515
  term p
    doc 1
      freq 4
      pos 4038
      pos 8915
      pos 8978
      pos 9151
    doc 2
      freq 9
      pos 2308
      pos 2802
      pos 2900
      pos 2991
      pos 3095
      pos 3139
      pos 3160
      pos 3308
      pos 3331
    doc 3
      freq 7
      pos 873
      pos 877
      pos 890
      pos 894
      pos 4518
      pos 4574
      pos 4613
    doc 6
      freq 4
      pos 1712
      pos 1795
      pos 1810
      pos 3012
    doc 8
      freq 2
      pos 1868
      pos 2020
    doc 9
      freq 1
      pos 1739
    doc 10
      freq 9
      pos 1483
      pos 8052
      pos 8063
      pos 8099
      pos 12708
      pos 12767
      pos 13188
      pos 13257
      pos 13339
    doc 11
      freq 2
      pos 9621
      pos 10286
    doc 12
      freq 9
      pos 15
      pos 6999
      pos 7013
      pos 7088
      pos 7355
      pos 7475
      pos 7492
      pos 7531
      pos 7747
    doc 13
      freq 3
      pos 16
      pos 6861
      pos 6892
    doc 14
      freq 24
      pos 588
      pos 604
      pos 694
      pos 1195
      pos 1246
      pos 1333
      pos 1388
      pos 1470
      pos 1771
      pos 1774
      pos 2965
      pos 3248
      pos 3284
      pos 3570
      pos 3876
      pos 4885
      pos 4984
      pos 5005
      pos 5022
      pos 5054
      pos 5364
      pos 5378
      pos 5409
      pos 5492
    doc 16
      freq 3
      pos 3
      pos 2561
      pos 2609
    skipList 
      level 0
        skipDoc 11
        skipDocFP 1711743
        impacts 
          impact 
            freq 1
            norm 95
          impact 
            freq 2
            norm 97
          impact 
            freq 4
            norm 101
          impact 
            freq 7
            norm 107
          impact 
            freq 9
            norm 108
        impactsEnd 
  term p.o
    doc 13
      freq 2
      pos 7012
      pos 7028
    doc 14
      freq 3
      pos 4274
      pos 4398
      pos 4490
  term p.ooooooooooooooooooooooooooooooooooooooooooooo
    doc 14
      freq 1
      pos 4263
  term p0a
    doc 11
      freq 1
      pos 10386
  term p0b7veqnf3f9w3
    doc 10
      freq 1
      pos 12702
  term p0fz4jco8mejtq2akxb81sfv2sx63dtofj6pg
    doc 10
      freq 1
      pos 12667
  term p2fauj28t94zedhn2vqzjfnhjco24kg3juf2t80ilp9yhcdwxjufrt86unlc
    doc 10
      freq 1
      pos 6911
  term p2pcircuit
    doc 0
      freq 1
      pos 7843
  term p4ndngz7zh0fijvpetjxkf
    doc 10
      freq 1
      pos 12778
  term p5dd
    doc 11
      freq 1
      pos 10008
  term p5xhbyoiz7i9xkkt6jiihvpfcyleven7qmbmwx5h5cgsidp0yl
    doc 11
      freq 1
      pos 9981
  term p802.11
    doc 2
      freq 2
      pos 2652
      pos 2690
  term p802.16
    doc 2
      freq 1
      pos 2745
  term p802.1q
    doc 2
      freq 1
      pos 2573
  term p802.1x
    doc 2
      freq 2
      pos 2495
      pos 2516
  term p82conuee0h9sfsfhiacw17nfwq
    doc 10
      freq 1
      pos 12467
  term p9yslsr3qc
    doc 11
      freq 1
      pos 10176
  term pa
    doc 1
      freq 3
      pos 9261
      pos 9277
      pos 9585
    doc 3
      freq 1
      pos 4791
    doc 10
      freq 1
      pos 12757
    doc 12
      freq 1
      pos 9435
  term pa33vmdb33nox
    doc 11
      freq 1
      pos 10263
  term packag
    doc 13
      freq 1
      pos 1860
  term packet
    doc 0
      freq 7
      pos 723
      pos 13219
      pos 13436
      pos 13522
      pos 13626
      pos 13716
      pos 16509
    doc 1
      freq 36
      pos 490
      pos 496
      pos 520
      pos 526
      pos 534
      pos 541
      pos 557
      pos 577
      pos 717
      pos 1235
      pos 1244
      pos 1362
      pos 1396
      pos 1412
      pos 1424
      pos 1440
      pos 1486
      pos 1494
      pos 1522
      pos 1541
      pos 1549
      pos 1562
      pos 6161
      pos 7458
      pos 7505
      pos 7532
      pos 7557
      pos 7569
      pos 7602
      pos 8081
      pos 8097
      pos 8105
      pos 8161
      pos 8171
      pos 8991
      pos 9008
    doc 3
      freq 13
      pos 379
      pos 1286
      pos 1307
      pos 1622
      pos 2194
      pos 2204
      pos 2206
      pos 2277
      pos 2635
      pos 3324
      pos 3354
      pos 3377
      pos 3415
    doc 4
      freq 67
      pos 192
      pos 770
      pos 1027
      pos 1036
      pos 1056
      pos 1181
      pos 1212
      pos 1223
      pos 1251
      pos 1401
      pos 1447
      pos 1449
      pos 1461
      pos 1499
      pos 1584
      pos 1614
      pos 1629
      pos 1663
      pos 1679
      pos 1730
      pos 1765
      pos 1785
      pos 2136
      pos 2142
      pos 2162
      pos 2250
      pos 2273
      pos 2412
      pos 2427
      pos 2511
      pos 2548
      pos 2574
      pos 2608
      pos 2754
      pos 2802
      pos 2808
      pos 2828
      pos 2858
      pos 2871
      pos 2878
      pos 2906
      pos 2937
      pos 2976
      pos 3047
      pos 3053
      pos 3073
      pos 3119
      pos 3141
      pos 3157
      pos 3283
      pos 3289
      pos 3309
      pos 3339
      pos 3355
      pos 3382
      pos 3403
      pos 3408
      pos 3504
      pos 3775
      pos 4031
      pos 4056
      pos 4250
      pos 4429
      pos 5631
      pos 5985
      pos 5996
      pos 6009
    doc 5
      freq 2
      pos 122
      pos 1294
    doc 6
      freq 29
      pos 222
      pos 322
      pos 337
      pos 386
      pos 685
      pos 930
      pos 969
      pos 973
      pos 1179
      pos 1220
      pos 1486
      pos 1602
      pos 1605
      pos 1664
      pos 1711
      pos 1761
      pos 1769
      pos 1843
      pos 1864
      pos 1966
      pos 1978
      pos 1988
      pos 2007
      pos 2082
      pos 2100
      pos 2108
      pos 2207
      pos 2412
      pos 3015
    doc 7
      freq 3
      pos 998
      pos 2147
      pos 2486
    doc 8
      freq 8
      pos 733
      pos 740
      pos 748
      pos 755
      pos 763
      pos 1881
      pos 1898
      pos 2029
    doc 11
      freq 1
      pos 3228
    doc 12
      freq 4
      pos 2744
      pos 8093
      pos 9241
      pos 9336
    skipList 
      level 0
        skipDoc 8
        skipDocFP 1715077
        impacts 
          impact 
            freq 8
            norm 97
          impact 
            freq 29
            norm 101
          impact 
            freq 67
            norm 108
        impactsEnd 
  term packet's
    doc 1
      freq 3
      pos 1755
      pos 8177
      pos 8340
    doc 4
      freq 3
      pos 3132
      pos 3419
      pos 3463
    doc 6
      freq 1
      pos 1294
  term packetcabl
    doc 6
      freq 1
      pos 2921
  term packets
    doc 0
      freq 4
      pos 5839
      pos 5889
      pos 6821
      pos 8259
    doc 1
      freq 12
      pos 857
      pos 872
      pos 921
      pos 943
      pos 1990
      pos 2022
      pos 6186
      pos 7434
      pos 7487
      pos 7581
      pos 7683
      pos 8140
    doc 3
      freq 4
      pos 1631
      pos 1651
      pos 3434
      pos 3459
    doc 4
      freq 6
      pos 488
      pos 1862
      pos 1910
      pos 4370
      pos 5655
      pos 5929
    doc 5
      freq 1
      pos 1432
    doc 6
      freq 20
      pos 568
      pos 939
      pos 1050
      pos 1060
      pos 1426
      pos 1705
      pos 1876
      pos 1938
      pos 1953
      pos 2054
      pos 2063
      pos 2065
      pos 2077
      pos 2096
      pos 2115
      pos 2121
      pos 2126
      pos 2131
      pos 2145
      pos 2442
    doc 8
      freq 1
      pos 1694
    doc 13
      freq 1
      pos 6484
    skipList 
      level 0
        skipDoc 13
        skipDocFP 1718386
        impacts 
          impact 
            freq 1
            norm 97
          impact 
            freq 20
            norm 101
        impactsEnd 
  term pad
    doc 7
      freq 1
      pos 1930
  term padded
    doc 0
      freq 2
      pos 6103
      pos 10688
  term padding
    doc 3
      freq 1
      pos 465
  term page
    doc 0
      freq 103
      pos 183
      pos 484
      pos 658
      pos 819
      pos 991
      pos 1200
      pos 1398
      pos 1610
      pos 1776
      pos 1917
      pos 2093
      pos 2325
      pos 2535
      pos 2716
      pos 2895
      pos 3083
      pos 3244
      pos 3455
      pos 3667
      pos 3802
      pos 4013
      pos 4198
      pos 4401
      pos 4544
      pos 4701
      pos 4817
      pos 5039
      pos 5233
      pos 5470
      pos 5584
      pos 5766
      pos 5947
      pos 6175
      pos 6340
      pos 6430
      pos 6650
      pos 6904
      pos 7083
      pos 7247
      pos 7348
      pos 7510
      pos 7675
      pos 7814
      pos 7948
      pos 8132
      pos 8327
      pos 8417
      pos 8636
      pos 8824
      pos 8924
      pos 9076
      pos 9241
      pos 9435
      pos 9591
      pos 9735
      pos 9901
      pos 10041
      pos 10167
      pos 10381
      pos 10580
      pos 10806
      pos 11018
      pos 11092
      pos 11300
      pos 11481
      pos 11639
      pos 11770
      pos 11876
      pos 12047
      pos 12174
      pos 12310
      pos 12463
      pos 12635
      pos 12783
      pos 12988
      pos 13179
      pos 13338
      pos 13538
      pos 13732
      pos 13922
      pos 14133
      pos 14320
      pos 14497
      pos 14663
      pos 14801
      pos 14921
      pos 15048
      pos 15175
      pos 15305
      pos 15416
      pos 15487
      pos 15558
      pos 15636
      pos 15720
      pos 15797
      pos 16129
      pos 16318
      pos 16470
      pos 16603
      pos 16841
      pos 17099
      pos 17214
      pos 17545
    doc 1
      freq 33
      pos 202
      pos 425
      pos 833
      pos 1062
      pos 1370
      pos 1863
      pos 2223
      pos 2419
      pos 2693
      pos 3052
      pos 3422
      pos 3607
      pos 3904
      pos 4241
      pos 4635
      pos 5015
      pos 5294
      pos 5686
      pos 6021
      pos 6362
      pos 6757
      pos 7195
      pos 7637
      pos 7887
      pos 8235
      pos 8703
      pos 9018
      pos 9222
      pos 9329
      pos 9399
      pos 9494
      pos 9595
      pos 9928
    doc 2
      freq 25
      pos 193
      pos 494
      pos 517
      pos 622
      pos 1072
      pos 1466
      pos 1841
      pos 2214
      pos 2451
      pos 2695
      pos 2819
      pos 2944
      pos 3200
      pos 3441
      pos 3484
      pos 3867
      pos 4251
      pos 4659
      pos 5020
      pos 5416
      pos 5821
      pos 6214
      pos 6328
      pos 6391
      pos 6722
    doc 3
      freq 24
      pos 165
      pos 330
      pos 577
      pos 757
      pos 1036
      pos 1422
      pos 1775
      pos 2114
      pos 2425
      pos 2820
      pos 3204
      pos 3613
      pos 4007
      pos 4295
      pos 4556
      pos 4737
      pos 4830
      pos 4934
      pos 4999
      pos 5195
      pos 5585
      pos 5786
      pos 5942
      pos 6277
    doc 4
      freq 24
      pos 138
      pos 419
      pos 739
      pos 1008
      pos 1365
      pos 1752
      pos 2074
      pos 2311
      pos 2715
      pos 2961
      pos 3198
      pos 3434
      pos 3624
      pos 3796
      pos 4086
      pos 4496
      pos 4882
      pos 5153
      pos 5398
      pos 5528
      pos 5813
      pos 6032
      pos 6098
      pos 6432
    doc 5
      freq 18
      pos 246
      pos 349
      pos 785
      pos 1142
      pos 1473
      pos 1740
      pos 2043
      pos 2354
      pos 2551
      pos 2732
      pos 3046
      pos 3356
      pos 3657
      pos 3909
      pos 4109
      pos 4345
      pos 4430
      pos 4761
    doc 6
      freq 10
      pos 285
      pos 738
      pos 1128
      pos 1609
      pos 2024
      pos 2338
      pos 2754
      pos 3031
      pos 3221
      pos 3560
    doc 7
      freq 11
      pos 198
      pos 585
      pos 949
      pos 1299
      pos 1647
      pos 1821
      pos 2175
      pos 2533
      pos 2888
      pos 2935
      pos 3265
    doc 8
      freq 9
      pos 183
      pos 470
      pos 795
      pos 1122
      pos 1436
      pos 1666
      pos 1927
      pos 2150
      pos 2483
    doc 9
      freq 7
      pos 228
      pos 591
      pos 932
      pos 1368
      pos 1723
      pos 1794
      pos 2127
    doc 10
      freq 41
      pos 170
      pos 394
      pos 785
      pos 1248
      pos 1699
      pos 2086
      pos 2512
      pos 2967
      pos 3371
      pos 3783
      pos 4182
      pos 4593
      pos 4937
      pos 5397
      pos 5762
      pos 6052
      pos 6270
      pos 6523
      pos 6778
      pos 6964
      pos 7268
      pos 7598
      pos 8030
      pos 8464
      pos 8984
      pos 9474
      pos 9939
      pos 10329
      pos 10785
      pos 11202
      pos 11540
      pos 11835
      pos 12092
      pos 12383
      pos 12530
      pos 12694
      pos 12829
      pos 13079
      pos 13329
      pos 13458
      pos 13789
    doc 11
      freq 53
      pos 187
      pos 490
      pos 817
      pos 1043
      pos 1250
      pos 1436
      pos 1570
      pos 1894
      pos 2108
      pos 2288
      pos 2540
      pos 2781
      pos 3049
      pos 3316
      pos 3439
      pos 3684
      pos 3880
      pos 3981
      pos 4167
      pos 4407
      pos 4650
      pos 4888
      pos 5066
      pos 5233
      pos 5390
      pos 5538
      pos 5698
      pos 5830
      pos 6018
      pos 6242
      pos 6478
      pos 6714
      pos 6928
      pos 7138
      pos 7266
      pos 7544
      pos 7778
      pos 8025
      pos 8222
      pos 8454
      pos 8638
      pos 8857
      pos 8956
      pos 9201
      pos 9411
      pos 9718
      pos 9856
      pos 10022
      pos 10212
      pos 10421
      pos 10514
      pos 10617
      pos 10950
    doc 12
      freq 29
      pos 235
      pos 497
      pos 861
      pos 1219
      pos 1556
      pos 1941
      pos 2275
      pos 2646
      pos 3018
      pos 3382
      pos 3811
      pos 4193
      pos 4558
      pos 5009
      pos 5418
      pos 5854
      pos 6244
      pos 6637
      pos 6982
      pos 7229
      pos 7458
      pos 7702
      pos 7882
      pos 8235
      pos 8632
      pos 9044
      pos 9416
      pos 9467
      pos 9800
    doc 13
      freq 23
      pos 120
      pos 350
      pos 754
      pos 1136
      pos 1457
      pos 1816
      pos 2168
      pos 2560
      pos 2931
      pos 3298
      pos 3659
      pos 3960
      pos 4295
      pos 4670
      pos 5015
      pos 5377
      pos 5727
      pos 6006
      pos 6328
      pos 6650
      pos 6940
      pos 7080
      pos 7415
    doc 14
      freq 23
      pos 213
      pos 556
      pos 840
      pos 1217
      pos 1546
      pos 1867
      pos 2157
      pos 2548
      pos 2902
      pos 3255
      pos 3539
      pos 3837
      pos 4133
      pos 4219
      pos 4284
      pos 4406
      pos 4500
      pos 4582
      pos 4960
      pos 5188
      pos 5454
      pos 5547
      pos 5880
    doc 15
      freq 14
      pos 190
      pos 301
      pos 631
      pos 1021
      pos 1389
      pos 1749
      pos 2144
      pos 2590
      pos 3002
      pos 3403
      pos 3798
      pos 4004
      pos 4067
      pos 4400
    doc 16
      freq 13
      pos 165
      pos 531
      pos 906
      pos 1311
      pos 1566
      pos 1685
      pos 1853
      pos 2111
      pos 2248
      pos 2510
      pos 2639
      pos 2679
      pos 3010
    doc 17
      freq 11
      pos 153
      pos 512
      pos 812
      pos 1050
      pos 1396
      pos 1845
      pos 2110
      pos 2148
      pos 2317
      pos 2403
      pos 2735
    doc 18
      freq 8
      pos 243
      pos 619
      pos 1027
      pos 1382
      pos 1809
      pos 2149
      pos 2192
      pos 2523
    skipList 
      level 0
        skipDoc 7
        skipDocFP 1719708
        impacts 
          impact 
            freq 11
            norm 100
          impact 
            freq 18
            norm 104
          impact 
            freq 24
            norm 107
          impact 
            freq 25
            norm 108
          impact 
            freq 33
            norm 113
          impact 
            freq 103
            norm 120
        impactsEnd 
        skipDoc 15
        skipDocFP 1723641
        impacts 
          impact 
            freq 7
            norm 95
          impact 
            freq 9
            norm 97
          impact 
            freq 14
            norm 104
          impact 
            freq 23
            norm 107
          impact 
            freq 29
            norm 113
          impact 
            freq 53
            norm 114
        impactsEnd 
  term pages
    doc 4
      freq 1
      pos 4928
    doc 13
      freq 3
      pos 470
      pos 641
      pos 778
  term paila
    doc 13
      freq 1
      pos 6974
  term pair
    doc 0
      freq 4
      pos 3209
      pos 3860
      pos 4360
      pos 11224
    doc 1
      freq 2
      pos 2946
      pos 3367
    doc 3
      freq 1
      pos 505
    doc 10
      freq 2
      pos 6196
      pos 6824
    doc 11
      freq 2
      pos 1023
      pos 1676
  term pairs
    doc 5
      freq 1
      pos 1788
    doc 10
      freq 1
      pos 12304
    doc 11
      freq 1
      pos 1827
  term pairwis
    doc 5
      freq 1
      pos 395
  term par
    doc 2
      freq 2
      pos 1093
      pos 1125
    doc 11
      freq 2
      pos 3501
      pos 3509
  term paradigms
    doc 15
      freq 1
      pos 2528
  term paragraph
    doc 1
      freq 1
      pos 6644
    doc 4
      freq 1
      pos 4378
  term paragraphs
    doc 8
      freq 1
      pos 347
  term parallel
    doc 2
      freq 2
      pos 3727
      pos 5226
    doc 12
      freq 2
      pos 1870
      pos 3532
    doc 15
      freq 1
      pos 3784
  term parallelism
    doc 12
      freq 1
      pos 3560
  term param
    doc 5
      freq 5
      pos 1615
      pos 1619
      pos 1717
      pos 1749
      pos 1764
    doc 10
      freq 1
      pos 4850
    doc 11
      freq 4
      pos 1304
      pos 8671
      pos 8676
      pos 8719
  term parameter
    doc 1
      freq 21
      pos 2103
      pos 2499
      pos 2623
      pos 2764
      pos 2788
      pos 2841
      pos 4589
      pos 5350
      pos 5522
      pos 5657
      pos 6078
      pos 6107
      pos 6110
      pos 6179
      pos 6196
      pos 6243
      pos 6256
      pos 6415
      pos 6441
      pos 7177
      pos 7312
    doc 3
      freq 6
      pos 213
      pos 1931
      pos 1980
      pos 1995
      pos 2030
      pos 2101
    doc 4
      freq 6
      pos 203
      pos 783
      pos 1698
      pos 3236
      pos 3414
      pos 4458
    doc 5
      freq 22
      pos 265
      pos 269
      pos 524
      pos 579
      pos 740
      pos 1026
      pos 1078
      pos 1112
      pos 1182
      pos 1482
      pos 1841
      pos 1862
      pos 2297
      pos 2344
      pos 2392
      pos 2401
      pos 2473
      pos 2897
      pos 3031
      pos 3146
      pos 3223
      pos 3350
    doc 8
      freq 4
      pos 821
      pos 999
      pos 1007
      pos 1093
    doc 10
      freq 18
      pos 354
      pos 2768
      pos 2851
      pos 5433
      pos 5458
      pos 5496
      pos 5733
      pos 9421
      pos 9424
      pos 9445
      pos 9508
      pos 11953
      pos 11979
      pos 11986
      pos 12008
      pos 12021
      pos 12063
      pos 12079
    doc 11
      freq 28
      pos 484
      pos 505
      pos 1278
      pos 1328
      pos 1335
      pos 1658
      pos 1721
      pos 1744
      pos 2082
      pos 2747
      pos 2759
      pos 2908
      pos 2916
      pos 3463
      pos 4785
      pos 4883
      pos 7040
      pos 7084
      pos 8654
      pos 8664
      pos 8690
      pos 8702
      pos 8720
      pos 8768
      pos 8781
      pos 8799
      pos 8810
      pos 9182
    doc 15
      freq 1
      pos 2114
    doc 16
      freq 1
      pos 1296
    skipList 
      level 0
        skipDoc 15
        skipDocFP 1729698
        impacts 
          impact 
            freq 4
            norm 97
          impact 
            freq 22
            norm 104
          impact 
            freq 28
            norm 114
        impactsEnd 
  term parameterized
    doc 6
      freq 1
      pos 710
  term parameternamewithnovalu
    doc 11
      freq 1
      pos 2837
  term parameters
    doc 0
      freq 1
      pos 15617
    doc 1
      freq 23
      pos 275
      pos 313
      pos 758
      pos 2302
      pos 2591
      pos 2777
      pos 2807
      pos 2818
      pos 3025
      pos 3043
      pos 3862
      pos 3946
      pos 3964
      pos 3966
      pos 4066
      pos 5562
      pos 5738
      pos 5968
      pos 5976
      pos 6120
      pos 6126
      pos 7237
      pos 7787
    doc 2
      freq 1
      pos 6314
    doc 3
      freq 3
      pos 1945
      pos 2008
      pos 3250
    doc 4
      freq 2
      pos 1983
      pos 5066
    doc 5
      freq 39
      pos 184
      pos 546
      pos 553
      pos 568
      pos 575
      pos 757
      pos 764
      pos 861
      pos 865
      pos 895
      pos 907
      pos 921
      pos 1003
      pos 1012
      pos 1088
      pos 1101
      pos 1492
      pos 1730
      pos 1870
      pos 2882
      pos 2930
      pos 2984
      pos 3041
      pos 3119
      pos 3132
      pos 3169
      pos 3187
      pos 3192
      pos 3234
      pos 3241
      pos 3293
      pos 3367
      pos 3370
      pos 3424
      pos 3446
      pos 3557
      pos 3569
      pos 3616
      pos 3678
    doc 6
      freq 2
      pos 1027
      pos 2216
    doc 7
      freq 1
      pos 1237
    doc 8
      freq 2
      pos 132
      pos 807
    doc 10
      freq 14
      pos 348
      pos 2807
      pos 5448
      pos 5736
      pos 5757
      pos 11460
      pos 11472
      pos 11522
      pos 11625
      pos 11720
      pos 11821
      pos 11915
      pos 11929
      pos 11990
    doc 11
      freq 7
      pos 216
      pos 1319
      pos 1381
      pos 2076
      pos 3452
      pos 4238
      pos 4249
    doc 13
      freq 4
      pos 419
      pos 4736
      pos 5496
      pos 5500
    doc 15
      freq 1
      pos 2581
    doc 16
      freq 1
      pos 674
    skipList 
      level 0
        skipDoc 7
        skipDocFP 1731943
        impacts 
          impact 
            freq 1
            norm 100
          impact 
            freq 2
            norm 101
          impact 
            freq 39
            norm 104
        impactsEnd 
  term paramnam
    doc 11
      freq 1
      pos 2872
  term params
    doc 10
      freq 2
      pos 4825
      pos 4833
  term parent
    doc 0
      freq 1
      pos 10099
    doc 12
      freq 2
      pos 3087
      pos 3126
    doc 13
      freq 1
      pos 2261
    doc 18
      freq 1
      pos 1130
  term parenthesized
    doc 16
      freq 3
      pos 562
      pos 651
      pos 724
  term park
    doc 1
      freq 1
      pos 9317
    doc 2
      freq 1
      pos 2869
    doc 3
      freq 1
      pos 4818
  term parker
    doc 0
      freq 107
      pos 4
      pos 180
      pos 481
      pos 655
      pos 816
      pos 988
      pos 1106
      pos 1197
      pos 1395
      pos 1607
      pos 1773
      pos 1914
      pos 2090
      pos 2322
      pos 2532
      pos 2713
      pos 2892
      pos 3080
      pos 3241
      pos 3452
      pos 3664
      pos 3799
      pos 4010
      pos 4195
      pos 4398
      pos 4541
      pos 4698
      pos 4814
      pos 5036
      pos 5230
      pos 5467
      pos 5581
      pos 5763
      pos 5944
      pos 6172
      pos 6337
      pos 6427
      pos 6647
      pos 6901
      pos 7080
      pos 7244
      pos 7345
      pos 7507
      pos 7672
      pos 7811
      pos 7945
      pos 8129
      pos 8324
      pos 8414
      pos 8633
      pos 8821
      pos 8921
      pos 9073
      pos 9238
      pos 9432
      pos 9588
      pos 9732
      pos 9898
      pos 10038
      pos 10164
      pos 10378
      pos 10577
      pos 10803
      pos 11015
      pos 11089
      pos 11297
      pos 11478
      pos 11636
      pos 11767
      pos 11873
      pos 12044
      pos 12171
      pos 12307
      pos 12460
      pos 12632
      pos 12780
      pos 12985
      pos 13176
      pos 13335
      pos 13535
      pos 13729
      pos 13919
      pos 14130
      pos 14317
      pos 14494
      pos 14660
      pos 14798
      pos 14918
      pos 15045
      pos 15172
      pos 15302
      pos 15413
      pos 15484
      pos 15555
      pos 15633
      pos 15717
      pos 15794
      pos 16126
      pos 16315
      pos 16467
      pos 16600
      pos 16838
      pos 17096
      pos 17138
      pos 17198
      pos 17211
      pos 17542
  term parkridg
    doc 3
      freq 1
      pos 4906
  term parkway
    doc 3
      freq 1
      pos 4892
  term pars
    doc 2
      freq 2
      pos 1007
      pos 1037
  term parse
    doc 0
      freq 2
      pos 7363
      pos 14270
    doc 11
      freq 2
      pos 1413
      pos 3493
  term parser
    doc 11
      freq 18
      pos 128
      pos 633
      pos 639
      pos 1193
      pos 2119
      pos 2502
      pos 3740
      pos 3972
      pos 4091
      pos 7013
      pos 7047
      pos 7160
      pos 7294
      pos 7440
      pos 7806
      pos 7914
      pos 9369
      pos 9538
  term parsers
    doc 11
      freq 7
      pos 2319
      pos 3580
      pos 3726
      pos 6402
      pos 7582
      pos 8400
      pos 9327
  term parsippany
    doc 11
      freq 1
      pos 10571
  term part
    doc 0
      freq 4
      pos 1222
      pos 3223
      pos 10434
      pos 10750
    doc 1
      freq 5
      pos 2033
      pos 2677
      pos 2792
      pos 3728
      pos 4218
    doc 2
      freq 16
      pos 1252
      pos 1753
      pos 1807
      pos 2541
      pos 2597
      pos 2638
      pos 2672
      pos 2715
      pos 3814
      pos 4372
      pos 4395
      pos 4522
      pos 4615
      pos 4726
      pos 5379
      pos 6057
    doc 3
      freq 4
      pos 2623
      pos 3128
      pos 4428
      pos 4472
    doc 4
      freq 3
      pos 505
      pos 2896
      pos 4487
    doc 5
      freq 9
      pos 1429
      pos 1765
      pos 2278
      pos 2303
      pos 2602
      pos 2608
      pos 3057
      pos 3105
      pos 3536
    doc 6
      freq 2
      pos 1661
      pos 1669
    doc 7
      freq 9
      pos 291
      pos 802
      pos 817
      pos 831
      pos 845
      pos 2212
      pos 2227
      pos 2241
      pos 2255
    doc 9
      freq 1
      pos 990
    doc 10
      freq 1
      pos 9919
    doc 11
      freq 8
      pos 220
      pos 1686
      pos 2171
      pos 3456
      pos 3468
      pos 3498
      pos 3707
      pos 9337
    doc 12
      freq 1
      pos 2039
    doc 13
      freq 1
      pos 5425
    doc 15
      freq 1
      pos 3177
    doc 16
      freq 16
      pos 588
      pos 772
      pos 797
      pos 815
      pos 889
      pos 1022
      pos 1107
      pos 1132
      pos 1284
      pos 1479
      pos 1482
      pos 1484
      pos 1893
      pos 2146
      pos 2224
      pos 2580
    skipList 
      level 0
        skipDoc 7
        skipDocFP 1737080
        impacts 
          impact 
            freq 9
            norm 100
          impact 
            freq 16
            norm 108
        impactsEnd 
  term partain
    doc 0
      freq 1
      pos 17177
  term partaking
    doc 0
      freq 1
      pos 6751
  term partial
    doc 0
      freq 1
      pos 7171
    doc 13
      freq 1
      pos 6555
  term partially
    doc 12
      freq 1
      pos 3530
  term partialsnpinterval
    doc 0
      freq 1
      pos 7186
  term participant
    doc 2
      freq 2
      pos 4429
      pos 5200
  term participants
    doc 2
      freq 14
      pos 209
      pos 455
      pos 916
      pos 1803
      pos 3730
      pos 4051
      pos 4215
      pos 4796
      pos 4872
      pos 5341
      pos 5375
      pos 5620
      pos 5686
      pos 6247
    doc 13
      freq 1
      pos 3210
  term participat
    doc 2
      freq 1
      pos 926
  term participating
    doc 5
      freq 2
      pos 687
      pos 3344
  term participation
    doc 7
      freq 2
      pos 527
      pos 1774
  term particular
    doc 0
      freq 2
      pos 696
      pos 17330
    doc 1
      freq 29
      pos 231
      pos 515
      pos 751
      pos 1443
      pos 1578
      pos 1978
      pos 2130
      pos 2134
      pos 2158
      pos 2177
      pos 2184
      pos 2670
      pos 2745
      pos 3218
      pos 3377
      pos 3459
      pos 3725
      pos 3784
      pos 3870
      pos 4483
      pos 4507
      pos 4521
      pos 4669
      pos 5328
      pos 7131
      pos 8764
      pos 8786
      pos 8792
      pos 9711
    doc 2
      freq 2
      pos 1054
      pos 6508
    doc 3
      freq 5
      pos 195
      pos 1691
      pos 2693
      pos 3011
      pos 6060
    doc 4
      freq 2
      pos 4670
      pos 6215
    doc 5
      freq 2
      pos 624
      pos 4545
    doc 6
      freq 3
      pos 94
      pos 249
      pos 3345
    doc 7
      freq 1
      pos 3050
    doc 8
      freq 2
      pos 434
      pos 2267
    doc 9
      freq 6
      pos 424
      pos 1069
      pos 1261
      pos 1463
      pos 1534
      pos 1912
    doc 10
      freq 12
      pos 924
      pos 1087
      pos 1182
      pos 1911
      pos 2725
      pos 8313
      pos 8721
      pos 9644
      pos 9798
      pos 10903
      pos 10911
      pos 13573
    doc 11
      freq 7
      pos 1604
      pos 2764
      pos 3753
      pos 3956
      pos 4633
      pos 8985
      pos 10734
    doc 12
      freq 5
      pos 801
      pos 6861
      pos 8284
      pos 8300
      pos 9584
    doc 13
      freq 2
      pos 4793
      pos 7199
    doc 14
      freq 1
      pos 5665
    doc 15
      freq 5
      pos 1802
      pos 2113
      pos 2624
      pos 3039
      pos 4184
    doc 16
      freq 2
      pos 1090
      pos 2795
    doc 17
      freq 6
      pos 318
      pos 412
      pos 759
      pos 1122
      pos 1185
      pos 2519
    doc 18
      freq 1
      pos 2307
    skipList 
      level 0
        skipDoc 7
        skipDocFP 1739765
        impacts 
          impact 
            freq 1
            norm 100
          impact 
            freq 3
            norm 101
          impact 
            freq 5
            norm 107
          impact 
            freq 29
            norm 113
        impactsEnd 
        skipDoc 15
        skipDocFP 1740632
        impacts 
          impact 
            freq 6
            norm 95
          impact 
            freq 7
            norm 114
          impact 
            freq 12
            norm 116
        impactsEnd 
  term particularly
    doc 2
      freq 1
      pos 1532
    doc 4
      freq 1
      pos 5471
    doc 11
      freq 2
      pos 706
      pos 6844
    doc 12
      freq 1
      pos 6362
  term parties
    doc 9
      freq 1
      pos 1429
    doc 12
      freq 1
      pos 6444
    doc 14
      freq 1
      pos 426
    doc 15
      freq 2
      pos 482
      pos 492
    doc 17
      freq 1
      pos 115
  term partition
    doc 0
      freq 1
      pos 7663
  term partitioned
    doc 0
      freq 1
      pos 16061
  term partnership
    doc 10
      freq 1
      pos 2887
    doc 12
      freq 1
      pos 7599
  term partridg
    doc 6
      freq 2
      pos 2894
      pos 2936
  term parts
    doc 0
      freq 3
      pos 16426
      pos 16442
      pos 16456
    doc 4
      freq 1
      pos 678
    doc 11
      freq 1
      pos 3704
    doc 12
      freq 2
      pos 1097
      pos 1100
    doc 13
      freq 7
      pos 2373
      pos 2505
      pos 5793
      pos 6073
      pos 6165
      pos 6246
      pos 6281
    doc 16
      freq 14
      pos 121
      pos 137
      pos 205
      pos 356
      pos 427
      pos 442
      pos 458
      pos 465
      pos 577
      pos 635
      pos 678
      pos 868
      pos 1153
      pos 1732
  term party
    doc 0
      freq 1
      pos 17487
    doc 1
      freq 1
      pos 9868
    doc 2
      freq 1
      pos 6665
    doc 3
      freq 1
      pos 6217
    doc 4
      freq 1
      pos 6372
    doc 5
      freq 1
      pos 4702
    doc 6
      freq 1
      pos 3502
    doc 7
      freq 1
      pos 3207
    doc 8
      freq 1
      pos 2424
    doc 9
      freq 2
      pos 444
      pos 2069
    doc 10
      freq 2
      pos 3707
      pos 13730
    doc 11
      freq 2
      pos 4419
      pos 10891
    doc 12
      freq 1
      pos 9741
    doc 13
      freq 2
      pos 4903
      pos 7356
    doc 14
      freq 1
      pos 5822
    doc 15
      freq 1
      pos 4341
    doc 16
      freq 1
      pos 2952
    doc 17
      freq 5
      pos 1070
      pos 1372
      pos 1736
      pos 1753
      pos 2676
    doc 18
      freq 1
      pos 2464
    skipList 
      level 0
        skipDoc 7
        skipDocFP 1743491
        impacts 
          impact 
            freq 1
            norm 100
        impactsEnd 
        skipDoc 15
        skipDocFP 1743796
        impacts 
          impact 
            freq 2
            norm 95
        impactsEnd 
  term pas
    doc 11
      freq 1
      pos 1923
  term pass
    doc 0
      freq 2
      pos 8204
      pos 14005
    doc 1
      freq 1
      pos 2825
    doc 4
      freq 1
      pos 1479
  term passed
    doc 3
      freq 1
      pos 2617
    doc 4
      freq 7
      pos 1392
      pos 2982
      pos 3218
      pos 3707
      pos 3970
      pos 3986
      pos 4571
    doc 10
      freq 2
      pos 10644
      pos 12358
    doc 11
      freq 2
      pos 9406
      pos 9775
    doc 12
      freq 1
      pos 3996
  term passes
    doc 3
      freq 1
      pos 1209
  term passing
    doc 0
      freq 1
      pos 16370
    doc 1
      freq 1
      pos 815
  term password
    doc 2
      freq 4
      pos 577
      pos 901
      pos 968
      pos 4087
    doc 7
      freq 1
      pos 2800
    doc 10
      freq 1
      pos 2713
    doc 12
      freq 1
      pos 5115
  term past
    doc 0
      freq 1
      pos 16084
    doc 2
      freq 2
      pos 781
      pos 1204
    doc 7
      freq 1
      pos 1498
  term paste
    doc 10
      freq 5
      pos 8278
      pos 8416
      pos 8583
      pos 8744
      pos 8870
  term pasted
    doc 10
      freq 2
      pos 8432
      pos 8673
  term pat
    doc 11
      freq 2
      pos 9586
      pos 9603
  term pate
    doc 1
      freq 2
      pos 8977
      pos 9152
    doc 3
      freq 2
      pos 4519
      pos 4575
    doc 8
      freq 2
      pos 1867
      pos 2021
  term patent
    doc 0
      freq 1
      pos 17497
    doc 1
      freq 1
      pos 9878
    doc 2
      freq 1
      pos 6675
    doc 3
      freq 1
      pos 6227
    doc 4
      freq 1
      pos 6382
    doc 5
      freq 1
      pos 4712
    doc 6
      freq 1
      pos 3512
    doc 7
      freq 1
      pos 3217
    doc 8
      freq 1
      pos 2434
    doc 9
      freq 1
      pos 2079
    doc 10
      freq 1
      pos 13740
    doc 11
      freq 1
      pos 10901
    doc 12
      freq 1
      pos 9751
    doc 13
      freq 1
      pos 7366
    doc 14
      freq 1
      pos 5832
    doc 15
      freq 1
      pos 4351
    doc 16
      freq 1
      pos 2962
    doc 17
      freq 1
      pos 2686
    doc 18
      freq 1
      pos 2474
    skipList 
      level 0
        skipDoc 7
        skipDocFP 1746097
        impacts 
          impact 
            freq 1
            norm 100
        impactsEnd 
        skipDoc 15
        skipDocFP 1746402
        impacts 
          impact 
            freq 1
            norm 95
        impactsEnd 
  term patents
    doc 0
      freq 1
      pos 17495
    doc 1
      freq 1
      pos 9876
    doc 2
      freq 1
      pos 6673
    doc 3
      freq 1
      pos 6225
    doc 4
      freq 1
      pos 6380
    doc 5
      freq 1
      pos 4710
    doc 6
      freq 1
      pos 3510
    doc 7
      freq 1
      pos 3215
    doc 8
      freq 1
      pos 2432
    doc 9
      freq 1
      pos 2077
    doc 10
      freq 1
      pos 13738
    doc 11
      freq 1
      pos 10899
    doc 12
      freq 1
      pos 9749
    doc 13
      freq 1
      pos 7364
    doc 14
      freq 1
      pos 5830
    doc 15
      freq 1
      pos 4349
    doc 16
      freq 1
      pos 2960
    doc 17
      freq 1
      pos 2684
    doc 18
      freq 1
      pos 2472
    skipList 
      level 0
        skipDoc 7
        skipDocFP 1747152
        impacts 
          impact 
            freq 1
            norm 100
        impactsEnd 
        skipDoc 15
        skipDocFP 1747457
        impacts 
          impact 
            freq 1
            norm 95
        impactsEnd 
  term path
    doc 0
      freq 1
      pos 10958
    doc 1
      freq 1
      pos 1267
    doc 3
      freq 5
      pos 3301
      pos 3346
      pos 3444
      pos 3464
      pos 4690
    doc 4
      freq 5
      pos 349
      pos 1687
      pos 2899
      pos 4507
      pos 5354
    doc 5
      freq 1
      pos 3579
    doc 10
      freq 1
      pos 4585
    doc 12
      freq 1
      pos 2429
    doc 15
      freq 6
      pos 237
      pos 650
      pos 1339
      pos 1344
      pos 1408
      pos 2083
    doc 16
      freq 2
      pos 1950
      pos 2318
    skipList 
      level 0
        skipDoc 15
        skipDocFP 1748204
        impacts 
          impact 
            freq 6
            norm 104
        impactsEnd 
  term paths
    doc 0
      freq 1
      pos 2479
  term patrik
    doc 2
      freq 1
      pos 6356
    doc 10
      freq 1
      pos 12123
  term patterns
    doc 9
      freq 1
      pos 1392
  term patton
    doc 12
      freq 2
      pos 6772
      pos 7058
  term paugh
    doc 12
      freq 1
      pos 7796
  term paul
    doc 2
      freq 5
      pos 837
      pos 3469
      pos 3471
      pos 3590
      pos 3631
    doc 6
      freq 1
      pos 3129
    doc 10
      freq 1
      pos 12125
  term pause
    doc 3
      freq 8
      pos 3180
      pos 5297
      pos 5318
      pos 5331
      pos 5357
      pos 5367
      pos 5375
      pos 5407
  term paxson
    doc 4
      freq 1
      pos 5309
  term paying
    doc 13
      freq 2
      pos 2480
      pos 6161
  term payload
    doc 1
      freq 6
      pos 1083
      pos 1084
      pos 1558
      pos 1610
      pos 1637
      pos 2016
    doc 3
      freq 5
      pos 1450
      pos 1467
      pos 2626
      pos 2878
      pos 3341
    doc 4
      freq 11
      pos 4047
      pos 4066
      pos 4228
      pos 4254
      pos 4277
      pos 4292
      pos 4306
      pos 4334
      pos 4615
      pos 5415
      pos 5835
    doc 5
      freq 28
      pos 278
      pos 296
      pos 1507
      pos 1543
      pos 1547
      pos 1568
      pos 1609
      pos 1621
      pos 1626
      pos 1632
      pos 1648
      pos 2274
      pos 2307
      pos 2383
      pos 2408
      pos 2567
      pos 2571
      pos 2588
      pos 2592
      pos 2646
      pos 2651
      pos 2656
      pos 2659
      pos 2668
      pos 2726
      pos 3736
      pos 3740
      pos 3757
    doc 6
      freq 4
      pos 1229
      pos 1256
      pos 1756
      pos 2826
    doc 8
      freq 1
      pos 1042
    doc 13
      freq 3
      pos 1787
      pos 5327
      pos 6538
  term payloads
    doc 1
      freq 2
      pos 625
      pos 630
    doc 5
      freq 4
      pos 196
      pos 1777
      pos 3435
      pos 3456
  term pbzl535
    doc 11
      freq 1
      pos 10244
  term pc
    doc 13
      freq 1
      pos 2604
  term pc33
    doc 10
      freq 14
      pos 6330
      pos 6364
      pos 6381
      pos 6389
      pos 6496
      pos 6506
      pos 6514
      pos 6615
      pos 6649
      pos 6681
      pos 6689
      pos 6974
      pos 7111
      pos 7324
  term pcdsqzaynppagmbaagjgbqwgbewhqydvr0obbyefnmu
    doc 10
      freq 1
      pos 6260
  term pcmu
    doc 10
      freq 3
      pos 6403
      pos 6540
      pos 6703
    doc 11
      freq 1
      pos 7888
  term pcoaic0k
    doc 10
      freq 1
      pos 6843
  term pcs
    doc 10
      freq 1
      pos 1691
  term pcst
    doc 5
      freq 2
      pos 2789
      pos 4255
  term pda8ojdfxzmnzfqhqqiaq2q6
    doc 11
      freq 1
      pos 9998
  term pdas
    doc 10
      freq 1
      pos 1693
    doc 13
      freq 1
      pos 916
  term pdf
    doc 2
      freq 3
      pos 2448
      pos 2770
      pos 2793
  term pdff3jy2529y5vawc4ahyh82
    doc 11
      freq 1
      pos 10116
  term pdp
    doc 12
      freq 1
      pos 9244
  term pdu
    doc 0
      freq 33
      pos 885
      pos 891
      pos 914
      pos 1507
      pos 1963
      pos 7628
      pos 7864
      pos 8063
      pos 8104
      pos 8158
      pos 8195
      pos 8379
      pos 10554
      pos 11610
      pos 11838
      pos 12378
      pos 12402
      pos 12429
      pos 12455
      pos 12491
      pos 12688
      pos 13088
      pos 13111
      pos 13117
      pos 13202
      pos 13291
      pos 13422
      pos 13508
      pos 13608
      pos 13698
      pos 13801
      pos 13993
      pos 14283
    doc 1
      freq 15
      pos 133
      pos 454
      pos 480
      pos 1135
      pos 1479
      pos 1569
      pos 1607
      pos 1615
      pos 6169
      pos 8008
      pos 8011
      pos 8014
      pos 8258
      pos 8309
      pos 8357
    doc 3
      freq 11
      pos 376
      pos 451
      pos 480
      pos 486
      pos 791
      pos 2876
      pos 2885
      pos 2903
      pos 4271
      pos 4286
      pos 4466
    doc 8
      freq 1
      pos 717
  term pdu's
    doc 1
      freq 1
      pos 8350
  term pdus
    doc 0
      freq 41
      pos 691
      pos 702
      pos 719
      pos 777
      pos 796
      pos 815
      pos 905
      pos 1375
      pos 1456
      pos 2637
      pos 5675
      pos 5811
      pos 6542
      pos 6855
      pos 6948
      pos 7174
      pos 8408
      pos 8455
      pos 8467
      pos 8523
      pos 8529
      pos 8580
      pos 8586
      pos 8783
      pos 9274
      pos 9393
      pos 9425
      pos 9471
      pos 9546
      pos 9580
      pos 9624
      pos 9654
      pos 9731
      pos 9769
      pos 9817
      pos 9849
      pos 9880
      pos 9931
      pos 10268
      pos 15689
      pos 16559
    doc 1
      freq 3
      pos 188
      pos 1199
      pos 8254
    doc 3
      freq 4
      pos 113
      pos 139
      pos 354
      pos 534
  term pe
    doc 1
      freq 22
      pos 3158
      pos 3185
      pos 3194
      pos 3460
      pos 4235
      pos 4362
      pos 4370
      pos 4383
      pos 4945
      pos 5029
      pos 5379
      pos 5634
      pos 5779
      pos 5794
      pos 5893
      pos 7354
      pos 8029
      pos 8251
      pos 8265
      pos 8280
      pos 8838
      pos 8866
    doc 3
      freq 44
      pos 234
      pos 528
      pos 871
      pos 872
      pos 922
      pos 958
      pos 1062
      pos 1492
      pos 1584
      pos 1730
      pos 1788
      pos 1866
      pos 1882
      pos 1895
      pos 2036
      pos 2052
      pos 2332
      pos 2419
      pos 2465
      pos 2481
      pos 2518
      pos 2566
      pos 2580
      pos 2694
      pos 2703
      pos 2738
      pos 2836
      pos 2856
      pos 3095
      pos 3177
      pos 3196
      pos 3573
      pos 3581
      pos 3787
      pos 3831
      pos 3860
      pos 3885
      pos 3904
      pos 3938
      pos 5325
      pos 5342
      pos 5363
      pos 5371
      pos 5813
    doc 17
      freq 6
      pos 506
      pos 522
      pos 543
      pos 2232
      pos 2287
      pos 2292
  term pe's
    doc 1
      freq 1
      pos 5365
  term pe1
    doc 1
      freq 21
      pos 1030
      pos 1118
      pos 1140
      pos 1143
      pos 1203
      pos 1223
      pos 1231
      pos 1474
      pos 1513
      pos 3380
      pos 3387
      pos 3394
      pos 3406
      pos 3414
      pos 4324
      pos 4329
      pos 4348
      pos 4363
      pos 4543
      pos 4721
      pos 4756
    doc 3
      freq 5
      pos 605
      pos 774
      pos 796
      pos 799
      pos 1908
  term pe2
    doc 1
      freq 36
      pos 1031
      pos 1127
      pos 1148
      pos 1153
      pos 1207
      pos 1225
      pos 1240
      pos 1348
      pos 1399
      pos 1409
      pos 1445
      pos 1481
      pos 1543
      pos 1544
      pos 1582
      pos 1585
      pos 1617
      pos 1643
      pos 3382
      pos 3389
      pos 3397
      pos 3404
      pos 3411
      pos 4328
      pos 4337
      pos 4384
      pos 4415
      pos 4422
      pos 4437
      pos 4454
      pos 4525
      pos 4536
      pos 4653
      pos 4697
      pos 4722
      pos 4766
    doc 3
      freq 5
      pos 606
      pos 783
      pos 803
      pos 812
      pos 1913
  term peer
    doc 0
      freq 6
      pos 1336
      pos 6632
      pos 12549
      pos 12556
      pos 12592
      pos 16255
    doc 1
      freq 9
      pos 4954
      pos 5219
      pos 5828
      pos 5830
      pos 5863
      pos 8500
      pos 8572
      pos 8766
      pos 8804
    doc 2
      freq 1
      pos 3344
    doc 5
      freq 3
      pos 616
      pos 618
      pos 1663
    doc 9
      freq 3
      pos 1262
      pos 1535
      pos 1547
  term peer's
    doc 1
      freq 1
      pos 4620
  term peers
    doc 0
      freq 3
      pos 9213
      pos 9222
      pos 16221
    doc 1
      freq 9
      pos 4822
      pos 5041
      pos 8505
      pos 8553
      pos 8598
      pos 8774
      pos 8813
      pos 8852
      pos 8862
    doc 5
      freq 2
      pos 2143
      pos 2993
    doc 13
      freq 1
      pos 527
  term pekka
    doc 2
      freq 1
      pos 6364
    doc 4
      freq 1
      pos 5498
    doc 7
      freq 1
      pos 1786
    doc 12
      freq 1
      pos 9454
    doc 13
      freq 1
      pos 7023
  term pekka.luom
    doc 13
      freq 1
      pos 7037
  term pem
    doc 7
      freq 1
      pos 1209
  term penalty
    doc 12
      freq 1
      pos 8833
  term penfield
    doc 11
      freq 1
      pos 9446
  term penno
    doc 11
      freq 1
      pos 9448
  term penultimat
    doc 1
      freq 2
      pos 890
      pos 1389
  term peopl
    doc 7
      freq 1
      pos 558
    doc 15
      freq 2
      pos 1123
      pos 3837
  term pepfu2xfu53
    doc 10
      freq 1
      pos 12736
  term perceiv
    doc 13
      freq 2
      pos 1647
      pos 1865
  term perceived
    doc 2
      freq 1
      pos 4125
  term perception
    doc 1
      freq 1
      pos 8044
    doc 13
      freq 1
      pos 1621
  term perfect
    doc 10
      freq 2
      pos 3256
      pos 9135
    doc 13
      freq 1
      pos 5117
    doc 18
      freq 4
      pos 854
      pos 1258
      pos 1596
      pos 1887
  term perform
    doc 4
      freq 3
      pos 491
      pos 4581
      pos 4601
    doc 5
      freq 4
      pos 2230
      pos 2465
      pos 2866
      pos 2999
    doc 10
      freq 2
      pos 2324
      pos 3916
    doc 12
      freq 4
      pos 97
      pos 3336
      pos 3415
      pos 6080
    doc 15
      freq 1
      pos 915
    doc 17
      freq 3
      pos 117
      pos 176
      pos 1515
  term performanc
    doc 6
      freq 3
      pos 2630
      pos 2653
      pos 3021
    doc 7
      freq 1
      pos 2080
    doc 12
      freq 7
      pos 2449
      pos 2455
      pos 3057
      pos 8618
      pos 8832
      pos 9031
      pos 9090
    doc 13
      freq 1
      pos 3873
  term performed
    doc 3
      freq 2
      pos 2784
      pos 2805
    doc 9
      freq 1
      pos 1002
    doc 10
      freq 5
      pos 2075
      pos 2570
      pos 2753
      pos 3015
      pos 12202
    doc 11
      freq 2
      pos 2102
      pos 9431
    doc 12
      freq 1
      pos 3481
    doc 16
      freq 1
      pos 993
  term performing
    doc 0
      freq 2
      pos 10420
      pos 10692
    doc 1
      freq 1
      pos 3599
    doc 6
      freq 1
      pos 2815
    doc 10
      freq 1
      pos 12909
    doc 11
      freq 1
      pos 9537
    doc 12
      freq 3
      pos 1865
      pos 3550
      pos 3876
  term performs
    doc 12
      freq 1
      pos 3667
  term perhaps
    doc 1
      freq 1
      pos 1658
    doc 3
      freq 1
      pos 5383
    doc 12
      freq 1
      pos 3954
    doc 15
      freq 3
      pos 765
      pos 1735
      pos 1797
  term period
    doc 0
      freq 3
      pos 6850
      pos 6872
      pos 6943
    doc 5
      freq 1
      pos 1415
    doc 6
      freq 7
      pos 1526
      pos 1552
      pos 1847
      pos 1869
      pos 2001
      pos 2369
      pos 2725
    doc 10
      freq 2
      pos 3277
      pos 4294
    doc 11
      freq 1
      pos 4441
    doc 12
      freq 1
      pos 5769
    doc 17
      freq 1
      pos 1548
  term periodic
    doc 0
      freq 2
      pos 7114
      pos 16075
    doc 9
      freq 1
      pos 180
    doc 13
      freq 1
      pos 4119
  term periodically
    doc 12
      freq 1
      pos 5918
  term periods
    doc 13
      freq 2
      pos 2130
      pos 4136
  term perkins
    doc 0
      freq 3
      pos 17042
      pos 17063
      pos 17081
    doc 9
      freq 10
      pos 4
      pos 225
      pos 588
      pos 929
      pos 1365
      pos 1652
      pos 1720
      pos 1766
      pos 1791
      pos 2124
    doc 12
      freq 1
      pos 7180
    doc 13
      freq 2
      pos 6774
      pos 6972
    doc 15
      freq 1
      pos 3946
  term perl
    doc 10
      freq 2
      pos 12364
      pos 12393
    doc 11
      freq 2
      pos 9781
      pos 9798
  term permanent
    doc 4
      freq 1
      pos 4919
  term permanently
    doc 4
      freq 1
      pos 4808
  term permission
    doc 0
      freq 1
      pos 17453
    doc 1
      freq 1
      pos 9834
    doc 2
      freq 2
      pos 1997
      pos 6631
    doc 3
      freq 1
      pos 6183
    doc 4
      freq 1
      pos 6338
    doc 5
      freq 1
      pos 4668
    doc 6
      freq 1
      pos 3468
    doc 7
      freq 1
      pos 3173
    doc 8
      freq 1
      pos 2390
    doc 9
      freq 1
      pos 2035
    doc 10
      freq 1
      pos 13696
    doc 11
      freq 1
      pos 10857
    doc 12
      freq 1
      pos 9707
    doc 13
      freq 1
      pos 7322
    doc 14
      freq 1
      pos 5788
    doc 15
      freq 1
      pos 4307
    doc 16
      freq 1
      pos 2918
    doc 17
      freq 1
      pos 2642
    doc 18
      freq 1
      pos 2430
    skipList 
      level 0
        skipDoc 7
        skipDocFP 1761044
        impacts 
          impact 
            freq 1
            norm 100
          impact 
            freq 2
            norm 108
        impactsEnd 
        skipDoc 15
        skipDocFP 1761364
        impacts 
          impact 
            freq 1
            norm 95
        impactsEnd 
  term permissions
    doc 10
      freq 1
      pos 11388
  term permit
    doc 0
      freq 1
      pos 2435
    doc 17
      freq 1
      pos 1414
  term permits
    doc 10
      freq 1
      pos 1900
  term permitted
    doc 0
      freq 1
      pos 2488
    doc 2
      freq 3
      pos 910
      pos 976
      pos 5676
    doc 10
      freq 3
      pos 2059
      pos 7709
      pos 13067
  term perrig
    doc 5
      freq 2
      pos 4183
      pos 4256
  term perryn
    doc 14
      freq 1
      pos 5530
  term persist
    doc 1
      freq 1
      pos 7441
  term person
    doc 8
      freq 4
      pos 604
      pos 982
      pos 1276
      pos 1471
  term person's
    doc 10
      freq 1
      pos 635
  term personal
    doc 2
      freq 1
      pos 4068
    doc 13
      freq 2
      pos 913
      pos 917
  term personally
    doc 9
      freq 1
      pos 581
  term perspectiv
    doc 1
      freq 2
      pos 3456
      pos 4447
    doc 10
      freq 1
      pos 1072
    doc 11
      freq 1
      pos 8251
    doc 12
      freq 2
      pos 2619
      pos 7915
    doc 15
      freq 1
      pos 1998
  term persson
    doc 10
      freq 1
      pos 12168
  term pertain
    doc 0
      freq 1
      pos 17357
    doc 1
      freq 1
      pos 9738
    doc 2
      freq 1
      pos 6535
    doc 3
      freq 1
      pos 6087
    doc 4
      freq 1
      pos 6242
    doc 5
      freq 1
      pos 4572
    doc 6
      freq 1
      pos 3372
    doc 7
      freq 1
      pos 3077
    doc 8
      freq 1
      pos 2294
    doc 9
      freq 1
      pos 1939
    doc 10
      freq 1
      pos 13600
    doc 11
      freq 1
      pos 10761
    doc 12
      freq 1
      pos 9611
    doc 13
      freq 1
      pos 7226
    doc 14
      freq 1
      pos 5692
    doc 15
      freq 1
      pos 4211
    doc 16
      freq 1
      pos 2822
    doc 17
      freq 1
      pos 2546
    doc 18
      freq 1
      pos 2334
    skipList 
      level 0
        skipDoc 7
        skipDocFP 1763347
        impacts 
          impact 
            freq 1
            norm 100
        impactsEnd 
        skipDoc 15
        skipDocFP 1763652
        impacts 
          impact 
            freq 1
            norm 95
        impactsEnd 
  term pertains
    doc 2
      freq 1
      pos 678
  term peruses
    doc 7
      freq 1
      pos 1176
  term pes
    doc 1
      freq 12
      pos 2068
      pos 2723
      pos 3976
      pos 4188
      pos 4260
      pos 4814
      pos 4942
      pos 5584
      pos 5616
      pos 5905
      pos 5987
      pos 7265
    doc 3
      freq 5
      pos 657
      pos 1569
      pos 1677
      pos 1956
      pos 3599
  term pete
    doc 2
      freq 1
      pos 6368
  term peter
    doc 0
      freq 1
      pos 15942
    doc 12
      freq 1
      pos 6804
    doc 16
      freq 1
      pos 2650
    doc 18
      freq 1
      pos 2017
  term petersburg
    doc 17
      freq 1
      pos 2378
  term peterson
    doc 5
      freq 1
      pos 4324
    doc 10
      freq 49
      pos 4
      pos 166
      pos 390
      pos 781
      pos 1244
      pos 1695
      pos 2082
      pos 2508
      pos 2963
      pos 3367
      pos 3779
      pos 4178
      pos 4589
      pos 4933
      pos 5393
      pos 5758
      pos 6048
      pos 6266
      pos 6519
      pos 6774
      pos 6960
      pos 7264
      pos 7594
      pos 8026
      pos 8460
      pos 8980
      pos 9470
      pos 9649
      pos 9935
      pos 10325
      pos 10781
      pos 11198
      pos 11536
      pos 11831
      pos 12088
      pos 12379
      pos 12526
      pos 12690
      pos 12825
      pos 13075
      pos 13099
      pos 13136
      pos 13169
      pos 13289
      pos 13325
      pos 13363
      pos 13406
      pos 13454
      pos 13785
    doc 11
      freq 2
      pos 9482
      pos 9638
    doc 13
      freq 1
      pos 6837
  term petit
    doc 11
      freq 2
      pos 9450
      pos 9484
  term petri
    doc 13
      freq 1
      pos 6969
  term petron
    doc 2
      freq 1
      pos 3332
  term pexpq8n4krm99orvq52dzpuqs009aqcflcrewn9w5q6cil8dz17jidiqv8qj
    doc 11
      freq 1
      pos 10478
  term pfb7n4p
    doc 11
      freq 1
      pos 9946
  term pflwywo5aaehp9xiqqlgq22smlweqsbazfrhyvenuzax5voqv
    doc 11
      freq 1
      pos 9907
  term pfpwlcargxqdwaa
    doc 11
      freq 1
      pos 10506
  term pfswwtelmakga1uebhmcvvmxczajbgnvbagmakdbmrawdgydvqqhdadbdgxhbnrh
    doc 10
      freq 1
      pos 6265
  term pfwft7v85wajvs94idepz3x
    doc 11
      freq 1
      pos 10350
  term pfznqs
    doc 11
      freq 1
      pos 9893
  term pgdcr
    doc 11
      freq 1
      pos 10470
  term phases
    doc 11
      freq 1
      pos 9554
  term phd
    doc 6
      freq 1
      pos 3151
  term phenomen
    doc 13
      freq 1
      pos 2084
  term phil
    doc 6
      freq 1
      pos 3123
  term philadelph
    doc 12
      freq 1
      pos 9434
  term phone
    doc 4
      freq 1
      pos 6085
    doc 6
      freq 2
      pos 3191
      pos 3211
    doc 7
      freq 1
      pos 2910
    doc 9
      freq 1
      pos 1778
    doc 10
      freq 3
      pos 7452
      pos 13418
      pos 13446
    doc 11
      freq 5
      pos 9259
      pos 9273
      pos 10549
      pos 10574
      pos 10602
    doc 14
      freq 2
      pos 5519
      pos 5536
    doc 16
      freq 1
      pos 2664
    skipList 
      level 0
        skipDoc 16
        skipDocFP 1767059
        impacts 
          impact 
            freq 1
            norm 95
          impact 
            freq 2
            norm 101
          impact 
            freq 5
            norm 114
        impactsEnd 
  term phones
    doc 10
      freq 1
      pos 1690
    doc 13
      freq 1
      pos 912
  term phras
    doc 10
      freq 5
      pos 3098
      pos 11632
      pos 11727
      pos 11828
      pos 11922
    doc 11
      freq 9
      pos 237
      pos 242
      pos 2190
      pos 3918
      pos 3925
      pos 3931
      pos 3945
      pos 4081
      pos 4089
  term phy
    doc 2
      freq 2
      pos 2649
      pos 2683
  term physical
    doc 1
      freq 5
      pos 1099
      pos 1101
      pos 2725
      pos 4190
      pos 8114
    doc 2
      freq 4
      pos 2611
      pos 2647
      pos 2681
      pos 2729
    doc 3
      freq 9
      pos 742
      pos 743
      pos 1000
      pos 1056
      pos 1795
      pos 4062
      pos 4442
      pos 4486
      pos 5158
    doc 12
      freq 1
      pos 3631
    doc 15
      freq 2
      pos 889
      pos 1848
  term pi.se
    doc 3
      freq 1
      pos 4993
  term piaidsbwfv1gerinxg8ewah6
    doc 10
      freq 1
      pos 12463
  term picked
    doc 0
      freq 1
      pos 9023
  term pickering
    doc 0
      freq 1
      pos 15957
  term piece
    doc 3
      freq 2
      pos 2367
      pos 2455
    doc 5
      freq 1
      pos 978
    doc 6
      freq 1
      pos 1210
    doc 12
      freq 1
      pos 3270
    doc 13
      freq 2
      pos 5936
      pos 5943
  term pieces
    doc 13
      freq 5
      pos 5908
      pos 5949
      pos 5957
      pos 6089
      pos 6225
    doc 16
      freq 1
      pos 274
  term pierr
    doc 13
      freq 1
      pos 6965
  term piggybacking
    doc 5
      freq 1
      pos 2523
  term pilot
    doc 12
      freq 1
      pos 2478
  term piloting
    doc 12
      freq 1
      pos 2353
  term ping
    doc 4
      freq 2
      pos 500
      pos 5677
  term pinkas
    doc 17
      freq 13
      pos 14
      pos 150
      pos 509
      pos 809
      pos 1047
      pos 1393
      pos 1842
      pos 2107
      pos 2145
      pos 2314
      pos 2385
      pos 2400
      pos 2732
  term pioneering
    doc 10
      freq 1
      pos 12159
  term piped
    doc 10
      freq 1
      pos 12375
    doc 11
      freq 1
      pos 9792
  term pittsburgh
    doc 1
      freq 2
      pos 9260
      pos 9276
    doc 3
      freq 1
      pos 4790
  term pizziment
    doc 11
      freq 1
      pos 9571
  term pj3d2ijzkxgnl6itkrn7gerh9psk0kzsqgfevrvsj4nopg
    doc 10
      freq 1
      pos 6872
  term pkc
    doc 17
      freq 7
      pos 170
      pos 220
      pos 1698
      pos 1732
      pos 1749
      pos 1757
      pos 1900
  term pkcs
    doc 17
      freq 1
      pos 1793
  term pkcs7
    doc 11
      freq 1
      pos 3537
  term pki
    doc 10
      freq 1
      pos 1673
    doc 17
      freq 2
      pos 1709
      pos 1774
  term pkix
    doc 10
      freq 1
      pos 5635
    doc 17
      freq 10
      pos 540
      pos 840
      pos 877
      pos 902
      pos 1978
      pos 2183
      pos 2223
      pos 2230
      pos 2248
      pos 2267
  term pkix1explicit88
    doc 17
      freq 1
      pos 2234
  term pkix1implicit88
    doc 17
      freq 1
      pos 2209
  term pkrs09w5diu4s50p0i1lgtmslrh4uyaijei0pbvh0z3vynexzlpcrtmqyyfu
    doc 11
      freq 1
      pos 9890
  term pkt
    doc 6
      freq 1
      pos 2927
  term place
    doc 0
      freq 3
      pos 1466
      pos 2181
      pos 2819
    doc 1
      freq 2
      pos 8591
      pos 9543
    doc 2
      freq 4
      pos 315
      pos 395
      pos 1324
      pos 3654
    doc 3
      freq 1
      pos 5908
    doc 5
      freq 1
      pos 640
    doc 10
      freq 5
      pos 1104
      pos 6138
      pos 7168
      pos 9642
      pos 10434
    doc 12
      freq 5
      pos 724
      pos 4954
      pos 5215
      pos 6511
      pos 6566
    doc 13
      freq 1
      pos 3908
    doc 15
      freq 1
      pos 1361
    doc 16
      freq 2
      pos 793
      pos 2497
    skipList 
      level 0
        skipDoc 13
        skipDocFP 1771042
        impacts 
          impact 
            freq 1
            norm 104
          impact 
            freq 4
            norm 108
          impact 
            freq 5
            norm 113
        impactsEnd 
  term placed
    doc 3
      freq 3
      pos 2361
      pos 2449
      pos 3807
    doc 5
      freq 1
      pos 889
    doc 9
      freq 1
      pos 662
    doc 10
      freq 3
      pos 4889
      pos 5548
      pos 6124
    doc 11
      freq 1
      pos 800
    doc 17
      freq 1
      pos 1591
  term places
    doc 10
      freq 2
      pos 459
      pos 1824
    doc 11
      freq 3
      pos 2019
      pos 2159
      pos 2417
    doc 13
      freq 1
      pos 1783
    doc 16
      freq 1
      pos 1169
  term plain
    doc 11
      freq 2
      pos 3860
      pos 8355
    doc 16
      freq 3
      pos 1735
      pos 2031
      pos 2211
  term plaintext
    doc 18
      freq 2
      pos 1726
      pos 1748
  term plan
    doc 11
      freq 2
      pos 722
      pos 726
  term plane
    doc 1
      freq 7
      pos 388
      pos 393
      pos 7983
      pos 7987
      pos 7990
      pos 8000
      pos 8404
    doc 6
      freq 1
      pos 818
  term planning
    doc 11
      freq 1
      pos 9397
  term platform
    doc 1
      freq 1
      pos 1766
  term plausibl
    doc 10
      freq 1
      pos 5712
  term players
    doc 13
      freq 1
      pos 3125
  term plaza
    doc 11
      freq 1
      pos 10570
  term pleas
    doc 0
      freq 3
      pos 51
      pos 213
      pos 17515
    doc 1
      freq 3
      pos 68
      pos 2568
      pos 9896
    doc 2
      freq 1
      pos 6693
    doc 3
      freq 2
      pos 62
      pos 6245
    doc 4
      freq 2
      pos 64
      pos 6400
    doc 5
      freq 2
      pos 48
      pos 4730
    doc 6
      freq 1
      pos 3530
    doc 7
      freq 1
      pos 3235
    doc 8
      freq 3
      pos 1640
      pos 1658
      pos 2452
    doc 9
      freq 2
      pos 50
      pos 2097
    doc 10
      freq 2
      pos 53
      pos 13758
    doc 11
      freq 1
      pos 10919
    doc 12
      freq 1
      pos 9769
    doc 13
      freq 1
      pos 7384
    doc 14
      freq 1
      pos 5850
    doc 15
      freq 1
      pos 4369
    doc 16
      freq 2
      pos 49
      pos 2980
    doc 17
      freq 2
      pos 46
      pos 2704
    doc 18
      freq 2
      pos 55
      pos 2492
    skipList 
      level 0
        skipDoc 7
        skipDocFP 1773179
        impacts 
          impact 
            freq 1
            norm 100
          impact 
            freq 2
            norm 104
          impact 
            freq 3
            norm 113
        impactsEnd 
        skipDoc 15
        skipDocFP 1773578
        impacts 
          impact 
            freq 2
            norm 95
          impact 
            freq 3
            norm 97
        impactsEnd 
  term plenaries
    doc 2
      freq 1
      pos 5669
  term plug
    doc 13
      freq 1
      pos 2323
  term plus
    doc 1
      freq 1
      pos 3259
    doc 2
      freq 2
      pos 416
      pos 443
    doc 13
      freq 1
      pos 1622
  term pmsy0dd3mhys7r2idcrwbjybljkgrkztve2h1yx1jugvdbwdcieyoz1wtg
    doc 11
      freq 1
      pos 10040
  term pmtu
    doc 4
      freq 3
      pos 360
      pos 2903
      pos 5346
  term pnco60tpneib4z7h4eawv5n6otgprvntcd0
    doc 10
      freq 1
      pos 12658
  term pnx
    doc 10
      freq 1
      pos 12476
  term po
    doc 13
      freq 1
      pos 7047
  term poayxlgkt
    doc 11
      freq 1
      pos 10483
  term pobox.example.com
    doc 12
      freq 3
      pos 2152
      pos 2168
      pos 2182
  term point
    doc 0
      freq 34
      pos 444
      pos 446
      pos 630
      pos 632
      pos 5369
      pos 5371
      pos 6524
      pos 6526
      pos 6538
      pos 6540
      pos 6621
      pos 6623
      pos 6661
      pos 6663
      pos 6877
      pos 6879
      pos 6890
      pos 6892
      pos 7860
      pos 7862
      pos 7877
      pos 7879
      pos 7886
      pos 7888
      pos 8240
      pos 8242
      pos 8463
      pos 8465
      pos 9192
      pos 9194
      pos 10306
      pos 10308
      pos 17164
      pos 17166
    doc 1
      freq 11
      pos 970
      pos 972
      pos 975
      pos 981
      pos 1325
      pos 1327
      pos 1332
      pos 1334
      pos 1342
      pos 1916
      pos 1918
    doc 2
      freq 7
      pos 1132
      pos 2407
      pos 2413
      pos 3791
      pos 6054
      pos 6064
      pos 6093
    doc 3
      freq 20
      pos 155
      pos 157
      pos 514
      pos 516
      pos 693
      pos 695
      pos 862
      pos 925
      pos 948
      pos 953
      pos 989
      pos 3167
      pos 3169
      pos 5029
      pos 5031
      pos 5143
      pos 5145
      pos 5449
      pos 5451
      pos 5815
    doc 4
      freq 6
      pos 2518
      pos 2520
      pos 3348
      pos 4931
      pos 5658
      pos 5660
    doc 5
      freq 3
      pos 662
      pos 664
      pos 2066
    doc 6
      freq 1
      pos 2323
    doc 7
      freq 10
      pos 888
      pos 890
      pos 2297
      pos 2299
      pos 2314
      pos 2316
      pos 2333
      pos 2335
      pos 2352
      pos 2354
    doc 8
      freq 2
      pos 407
      pos 419
    doc 10
      freq 1
      pos 10632
    doc 11
      freq 2
      pos 933
      pos 6581
    doc 12
      freq 4
      pos 2166
      pos 4299
      pos 5335
      pos 5401
    doc 13
      freq 1
      pos 5322
    doc 15
      freq 1
      pos 1989
    doc 16
      freq 1
      pos 2228
    skipList 
      level 0
        skipDoc 7
        skipDocFP 1775359
        impacts 
          impact 
            freq 10
            norm 100
          impact 
            freq 20
            norm 107
          impact 
            freq 34
            norm 120
        impactsEnd 
  term pointed
    doc 2
      freq 1
      pos 5132
    doc 7
      freq 1
      pos 1603
    doc 16
      freq 1
      pos 773
  term pointer
    doc 2
      freq 1
      pos 505
    doc 4
      freq 5
      pos 3278
      pos 3331
      pos 3346
      pos 3456
      pos 3486
    doc 12
      freq 1
      pos 5063
    doc 17
      freq 6
      pos 918
      pos 1002
      pos 1012
      pos 1016
      pos 1029
      pos 2348
  term pointers
    doc 12
      freq 1
      pos 531
    doc 13
      freq 2
      pos 6094
      pos 6232
  term pointing
    doc 12
      freq 1
      pos 4181
  term points
    doc 0
      freq 5
      pos 12697
      pos 12712
      pos 14296
      pos 14308
      pos 14344
    doc 2
      freq 4
      pos 3321
      pos 6076
      pos 6105
      pos 6114
    doc 3
      freq 4
      pos 1048
      pos 1161
      pos 1168
      pos 5038
    doc 8
      freq 1
      pos 403
    doc 11
      freq 1
      pos 9372
    doc 12
      freq 1
      pos 5087
  term policies
    doc 2
      freq 4
      pos 90
      pos 307
      pos 2884
      pos 2893
    doc 4
      freq 1
      pos 2622
    doc 5
      freq 3
      pos 1552
      pos 3770
      pos 3977
    doc 10
      freq 14
      pos 725
      pos 727
      pos 821
      pos 873
      pos 1208
      pos 2949
      pos 9756
      pos 9777
      pos 9827
      pos 9901
      pos 10886
      pos 10912
      pos 11065
      pos 11414
    doc 12
      freq 1
      pos 4647
    doc 17
      freq 34
      pos 21
      pos 96
      pos 158
      pos 216
      pos 233
      pos 241
      pos 252
      pos 296
      pos 420
      pos 439
      pos 457
      pos 500
      pos 517
      pos 548
      pos 555
      pos 570
      pos 586
      pos 598
      pos 606
      pos 700
      pos 742
      pos 817
      pos 1055
      pos 1260
      pos 1279
      pos 1401
      pos 1850
      pos 1947
      pos 1961
      pos 2115
      pos 2153
      pos 2191
      pos 2322
      pos 2408
    doc 18
      freq 2
      pos 281
      pos 297
  term policing
    doc 3
      freq 1
      pos 1011
  term policy
    doc 1
      freq 1
      pos 9169
    doc 2
      freq 3
      pos 711
      pos 1896
      pos 2875
    doc 3
      freq 2
      pos 4048
      pos 5840
    doc 4
      freq 4
      pos 2197
      pos 5024
      pos 5113
      pos 5701
    doc 5
      freq 30
      pos 276
      pos 282
      pos 527
      pos 583
      pos 1512
      pos 1532
      pos 1541
      pos 1546
      pos 1567
      pos 1610
      pos 1614
      pos 1618
      pos 1641
      pos 1647
      pos 1676
      pos 1716
      pos 1729
      pos 1748
      pos 1756
      pos 1763
      pos 1865
      pos 1867
      pos 2013
      pos 2023
      pos 2035
      pos 2273
      pos 2407
      pos 3935
      pos 3948
      pos 3971
    doc 7
      freq 5
      pos 363
      pos 899
      pos 905
      pos 2363
      pos 2369
    doc 8
      freq 14
      pos 528
      pos 548
      pos 577
      pos 858
      pos 878
      pos 908
      pos 1184
      pos 1204
      pos 1233
      pos 1365
      pos 1385
      pos 1414
      pos 1554
      pos 1750
    doc 10
      freq 16
      pos 1895
      pos 2445
      pos 2737
      pos 2757
      pos 2914
      pos 3085
      pos 3158
      pos 3871
      pos 3880
      pos 3886
      pos 4680
      pos 9789
      pos 9952
      pos 10346
      pos 11139
      pos 13071
    doc 12
      freq 2
      pos 6032
      pos 6104
    doc 17
      freq 16
      pos 208
      pos 302
      pos 377
      pos 764
      pos 775
      pos 783
      pos 833
      pos 941
      pos 955
      pos 959
      pos 968
      pos 977
      pos 986
      pos 1391
      pos 1823
      pos 2260
    skipList 
      level 0
        skipDoc 10
        skipDocFP 1779638
        impacts 
          impact 
            freq 14
            norm 97
          impact 
            freq 30
            norm 104
        impactsEnd 
  term policyidentifier
    doc 17
      freq 2
      pos 795
      pos 2303
  term policyinformation
    doc 17
      freq 4
      pos 792
      pos 793
      pos 2300
      pos 2301
  term policyqualifierid
    doc 17
      freq 8
      pos 823
      pos 824
      pos 829
      pos 908
      pos 2331
      pos 2332
      pos 2337
      pos 2338
  term policyqualifierids
    doc 17
      freq 2
      pos 830
      pos 2257
  term policyqualifierinf
    doc 17
      freq 4
      pos 803
      pos 821
      pos 2311
      pos 2329
  term policyqualifiers
    doc 17
      freq 2
      pos 797
      pos 2305
  term polk
    doc 10
      freq 1
      pos 13229
    doc 17
      freq 1
      pos 2049
  term polleshellorat
    doc 0
      freq 1
      pos 2652
  term polling
    doc 13
      freq 2
      pos 843
      pos 1745
  term ponging
    doc 4
      freq 1
      pos 5678
  term pools
    doc 1
      freq 1
      pos 3292
  term poor
    doc 18
      freq 1
      pos 1860
  term pop
    doc 15
      freq 1
      pos 2062
  term pop3
    doc 7
      freq 1
      pos 2606
  term popping
    doc 1
      freq 2
      pos 892
      pos 1391
  term populat
    doc 10
      freq 2
      pos 1187
      pos 4423
  term populated
    doc 10
      freq 4
      pos 476
      pos 499
      pos 841
      pos 1874
  term populates
    doc 10
      freq 1
      pos 1052
  term population
    doc 10
      freq 1
      pos 1237
    doc 12
      freq 1
      pos 1424
  term populations
    doc 13
      freq 1
      pos 4638
  term port
    doc 0
      freq 1
      pos 5965
    doc 1
      freq 5
      pos 2659
      pos 2726
      pos 4154
      pos 4165
      pos 4191
    doc 2
      freq 3
      pos 2468
      pos 2489
      pos 2510
    doc 3
      freq 19
      pos 919
      pos 932
      pos 1001
      pos 1277
      pos 1279
      pos 1543
      pos 1796
      pos 1799
      pos 1817
      pos 1874
      pos 1877
      pos 4063
      pos 5123
      pos 5151
      pos 5159
      pos 5338
      pos 5354
      pos 5382
      pos 5413
    doc 4
      freq 1
      pos 2189
    doc 8
      freq 1
      pos 724
    doc 11
      freq 1
      pos 7889
    doc 12
      freq 1
      pos 1598
    skipList 
      level 0
        skipDoc 12
        skipDocFP 1783016
        impacts 
          impact 
            freq 1
            norm 97
          impact 
            freq 19
            norm 107
        impactsEnd 
  term portfolio.html
    doc 2
      freq 1
      pos 2299
  term portion
    doc 0
      freq 1
      pos 93
    doc 3
      freq 1
      pos 851
    doc 10
      freq 14
      pos 2046
      pos 2395
      pos 2818
      pos 3041
      pos 4451
      pos 5042
      pos 5568
      pos 7442
      pos 7882
      pos 7929
      pos 9575
      pos 10384
      pos 10571
      pos 10808
    doc 11
      freq 1
      pos 2460
  term portions
    doc 0
      freq 3
      pos 1179
      pos 15874
      pos 16046
    doc 10
      freq 2
      pos 4982
      pos 5015
  term ports
    doc 1
      freq 2
      pos 3982
      pos 5993
    doc 3
      freq 1
      pos 1962
    doc 6
      freq 1
      pos 2607
  term pose
    doc 0
      freq 2
      pos 16650
      pos 16704
    doc 10
      freq 1
      pos 10095
  term poses
    doc 15
      freq 1
      pos 1132
  term position
    doc 0
      freq 1
      pos 17338
    doc 1
      freq 1
      pos 9719
    doc 2
      freq 1
      pos 6516
    doc 3
      freq 1
      pos 6068
    doc 4
      freq 1
      pos 6223
    doc 5
      freq 1
      pos 4553
    doc 6
      freq 1
      pos 3353
    doc 7
      freq 1
      pos 3058
    doc 8
      freq 1
      pos 2275
    doc 9
      freq 1
      pos 1920
    doc 10
      freq 2
      pos 11188
      pos 13581
    doc 11
      freq 1
      pos 10742
    doc 12
      freq 1
      pos 9592
    doc 13
      freq 1
      pos 7207
    doc 14
      freq 1
      pos 5673
    doc 15
      freq 2
      pos 3585
      pos 4192
    doc 16
      freq 1
      pos 2803
    doc 17
      freq 1
      pos 2527
    doc 18
      freq 1
      pos 2315
    skipList 
      level 0
        skipDoc 7
        skipDocFP 1784788
        impacts 
          impact 
            freq 1
            norm 100
        impactsEnd 
        skipDoc 15
        skipDocFP 1785093
        impacts 
          impact 
            freq 1
            norm 95
          impact 
            freq 2
            norm 104
        impactsEnd 
  term positions
    doc 0
      freq 1
      pos 10632
  term positiv
    doc 11
      freq 1
      pos 8597
  term possess
    doc 10
      freq 3
      pos 2135
      pos 7875
      pos 11791
  term possibilities
    doc 1
      freq 1
      pos 6781
    doc 12
      freq 1
      pos 3660
  term possibility
    doc 1
      freq 5
      pos 8248
      pos 8305
      pos 8347
      pos 8617
      pos 8662
    doc 10
      freq 1
      pos 11310
    doc 12
      freq 1
      pos 8938
    doc 14
      freq 2
      pos 2171
      pos 2230
    doc 17
      freq 1
      pos 1906
  term possibl
    doc 0
      freq 1
      pos 5268
    doc 1
      freq 6
      pos 142
      pos 917
      pos 7524
      pos 7603
      pos 8092
      pos 8761
    doc 2
      freq 2
      pos 924
      pos 2107
    doc 3
      freq 2
      pos 2080
      pos 5826
    doc 4
      freq 11
      pos 914
      pos 1455
      pos 1528
      pos 1609
      pos 2026
      pos 2138
      pos 2804
      pos 3049
      pos 3285
      pos 4579
      pos 5863
    doc 5
      freq 7
      pos 1785
      pos 1903
      pos 2093
      pos 2119
      pos 2251
      pos 2576
      pos 3745
    doc 6
      freq 2
      pos 957
      pos 2332
    doc 9
      freq 2
      pos 635
      pos 658
    doc 10
      freq 15
      pos 1430
      pos 2208
      pos 2562
      pos 7483
      pos 7649
      pos 7724
      pos 7906
      pos 8953
      pos 9045
      pos 10087
      pos 10206
      pos 10246
      pos 10296
      pos 11059
      pos 13030
    doc 11
      freq 1
      pos 6340
    doc 12
      freq 11
      pos 1378
      pos 1438
      pos 1857
      pos 1985
      pos 2414
      pos 3246
      pos 4575
      pos 5242
      pos 5568
      pos 5780
      pos 8707
    doc 13
      freq 26
      pos 2348
      pos 2762
      pos 4684
      pos 5125
      pos 5528
      pos 5560
      pos 5818
      pos 5835
      pos 5861
      pos 5875
      pos 5901
      pos 5927
      pos 5969
      pos 5984
      pos 6062
      pos 6084
      pos 6113
      pos 6204
      pos 6218
      pos 6239
      pos 6258
      pos 6271
      pos 6301
      pos 6346
      pos 6420
      pos 6443
    doc 14
      freq 18
      pos 190
      pos 366
      pos 513
      pos 719
      pos 736
      pos 862
      pos 885
      pos 900
      pos 1095
      pos 1537
      pos 2048
      pos 2099
      pos 2345
      pos 2568
      pos 2656
      pos 3870
      pos 4600
      pos 5048
    doc 15
      freq 4
      pos 965
      pos 1478
      pos 2180
      pos 2673
    doc 16
      freq 1
      pos 1267
    doc 18
      freq 6
      pos 137
      pos 260
      pos 331
      pos 883
      pos 1226
      pos 1919
    skipList 
      level 0
        skipDoc 9
        skipDocFP 1786514
        impacts 
          impact 
            freq 2
            norm 95
          impact 
            freq 7
            norm 104
          impact 
            freq 11
            norm 108
        impactsEnd 
        skipDoc 18
        skipDocFP 1787187
        impacts 
          impact 
            freq 6
            norm 97
          impact 
            freq 18
            norm 107
          impact 
            freq 26
            norm 109
        impactsEnd 
  term possibly
    doc 6
      freq 1
      pos 2311
    doc 10
      freq 2
      pos 1855
      pos 10108
    doc 13
      freq 4
      pos 513
      pos 831
      pos 2243
      pos 3022
    doc 14
      freq 1
      pos 2605
    doc 15
      freq 1
      pos 846
  term post
    doc 6
      freq 3
      pos 1729
      pos 1746
      pos 1799
  term posted
    doc 2
      freq 1
      pos 1039
  term postel
    doc 4
      freq 1
      pos 5214
  term posting
    doc 2
      freq 1
      pos 965
  term postmaster
    doc 7
      freq 2
      pos 1014
      pos 2554
  term potential
    doc 2
      freq 2
      pos 1148
      pos 1537
    doc 6
      freq 1
      pos 2695
    doc 10
      freq 4
      pos 794
      pos 3774
      pos 10716
      pos 11294
    doc 12
      freq 5
      pos 490
      pos 3140
      pos 9059
      pos 9089
      pos 9113
    doc 13
      freq 3
      pos 963
      pos 6464
      pos 6730
    doc 15
      freq 4
      pos 149
      pos 255
      pos 1760
      pos 2650
    doc 17
      freq 1
      pos 1814
  term potentially
    doc 1
      freq 1
      pos 7582
    doc 2
      freq 2
      pos 1708
      pos 5973
    doc 4
      freq 1
      pos 6022
    doc 10
      freq 3
      pos 1683
      pos 4387
      pos 8703
    doc 12
      freq 1
      pos 9103
    doc 13
      freq 2
      pos 677
      pos 1047
    doc 15
      freq 2
      pos 1277
      pos 2782
    doc 16
      freq 1
      pos 353
    doc 17
      freq 1
      pos 1421
    skipList 
      level 0
        skipDoc 16
        skipDocFP 1790220
        impacts 
          impact 
            freq 1
            norm 99
          impact 
            freq 2
            norm 104
          impact 
            freq 3
            norm 116
        impactsEnd 
  term power
    doc 2
      freq 3
      pos 275
      pos 3191
      pos 4005
    doc 13
      freq 1
      pos 4097
    doc 16
      freq 1
      pos 2227
  term powered
    doc 13
      freq 5
      pos 2072
      pos 2076
      pos 2125
      pos 4107
      pos 4166
  term powerpoint
    doc 16
      freq 1
      pos 2138
  term pp
    doc 5
      freq 1
      pos 4283
  term pp8syemjzowtncabmjmljbhsiwm1
    doc 10
      freq 1
      pos 12607
  term ppp
    doc 0
      freq 1
      pos 7990
    doc 1
      freq 1
      pos 9086
    doc 2
      freq 1
      pos 2960
    doc 7
      freq 17
      pos 754
      pos 996
      pos 1080
      pos 1089
      pos 2092
      pos 2114
      pos 2124
      pos 2484
      pos 2501
      pos 2526
      pos 2543
      pos 2562
      pos 2673
      pos 2682
      pos 2818
      pos 2835
      pos 2842
    doc 8
      freq 2
      pos 662
      pos 1975
  term ppp9r
    doc 11
      freq 1
      pos 10320
  term pppext
    doc 2
      freq 2
      pos 5162
      pos 5207
  term ppphdlc
    doc 1
      freq 2
      pos 439
      pos 9071
    doc 8
      freq 3
      pos 660
      pos 663
      pos 1960
  term ppqog1uxndzhbg7mr6rl9bnuhhufvrbp51mn3w0gfus
    doc 10
      freq 2
      pos 7282
      pos 7372
  term pra
    doc 10
      freq 2
      pos 5806
      pos 5837
  term practic
    doc 0
      freq 3
      pos 1196
      pos 1733
      pos 15897
    doc 1
      freq 1
      pos 8378
    doc 2
      freq 3
      pos 2402
      pos 6050
      pos 6296
    doc 7
      freq 4
      pos 88
      pos 1531
      pos 1575
      pos 1579
    doc 8
      freq 10
      pos 19
      pos 182
      pos 469
      pos 794
      pos 1121
      pos 1435
      pos 1665
      pos 1926
      pos 2149
      pos 2482
    doc 10
      freq 3
      pos 6134
      pos 9059
      pos 9601
    doc 12
      freq 2
      pos 5978
      pos 8508
    doc 15
      freq 4
      pos 1885
      pos 3062
      pos 3283
      pos 3699
    doc 17
      freq 1
      pos 1021
    skipList 
      level 0
        skipDoc 15
        skipDocFP 1792269
        impacts 
          impact 
            freq 10
            norm 97
        impactsEnd 
  term practical
    doc 6
      freq 1
      pos 352
    doc 10
      freq 1
      pos 1661
    doc 12
      freq 1
      pos 1491
  term practically
    doc 12
      freq 3
      pos 6690
      pos 6729
      pos 8910
  term practices
    doc 8
      freq 1
      pos 40
    doc 10
      freq 9
      pos 1284
      pos 3953
      pos 7782
      pos 9669
      pos 10987
      pos 11024
      pos 11051
      pos 11119
      pos 11158
  term pre
    doc 1
      freq 3
      pos 8508
      pos 8697
      pos 8728
    doc 6
      freq 5
      pos 1643
      pos 1725
      pos 1734
      pos 1749
      pos 1784
    doc 10
      freq 1
      pos 4560
    doc 12
      freq 2
      pos 4767
      pos 5991
    doc 13
      freq 3
      pos 233
      pos 3486
      pos 3557
  term preambl
    doc 3
      freq 3
      pos 1362
      pos 1410
      pos 2141
  term prearranged
    doc 10
      freq 1
      pos 582
  term precaution
    doc 1
      freq 1
      pos 7448
  term precautions
    doc 11
      freq 1
      pos 4612
  term preceded
    doc 4
      freq 1
      pos 537
    doc 14
      freq 1
      pos 2941
  term precedenc
    doc 3
      freq 4
      pos 323
      pos 5800
      pos 5808
      pos 5831
    doc 4
      freq 2
      pos 2044
      pos 5739
  term precedent
    doc 10
      freq 1
      pos 9594
  term preceding
    doc 4
      freq 1
      pos 564
    doc 18
      freq 2
      pos 1237
      pos 1876
  term precious
    doc 15
      freq 1
      pos 2783
  term precis
    doc 10
      freq 1
      pos 5308
  term precisely
    doc 10
      freq 1
      pos 3161
    doc 13
      freq 1
      pos 399
  term precision
    doc 0
      freq 1
      pos 2198
  term preclud
    doc 13
      freq 2
      pos 3771
      pos 3937
  term precomputabl
    doc 9
      freq 12
      pos 235
      pos 562
      pos 598
      pos 896
      pos 918
      pos 939
      pos 954
      pos 1021
      pos 1375
      pos 1581
      pos 1730
      pos 1801
  term precomputing
    doc 9
      freq 3
      pos 100
      pos 125
      pos 670
  term preconfigur
    doc 9
      freq 2
      pos 96
      pos 684
  term preconfiguration
    doc 9
      freq 1
      pos 312
  term preconfigured
    doc 9
      freq 3
      pos 795
      pos 827
      pos 1257
    doc 12
      freq 1
      pos 7762
  term predecessor
    doc 14
      freq 34
      pos 20
      pos 79
      pos 140
      pos 158
      pos 219
      pos 401
      pos 440
      pos 461
      pos 471
      pos 562
      pos 591
      pos 606
      pos 691
      pos 846
      pos 1223
      pos 1385
      pos 1552
      pos 1873
      pos 2163
      pos 2554
      pos 2908
      pos 3261
      pos 3545
      pos 3843
      pos 4139
      pos 4225
      pos 4290
      pos 4412
      pos 4506
      pos 4588
      pos 4966
      pos 5194
      pos 5460
      pos 5553
  term predecessors
    doc 14
      freq 8
      pos 234
      pos 251
      pos 1280
      pos 2396
      pos 2791
      pos 2956
      pos 4876
      pos 5281
  term predictability
    doc 15
      freq 1
      pos 2394
  term predictabl
    doc 12
      freq 1
      pos 5930
    doc 18
      freq 1
      pos 1718
  term preempting
    doc 10
      freq 1
      pos 9006
  term preexisting
    doc 10
      freq 1
      pos 3149
  term prefer
    doc 1
      freq 3
      pos 6725
      pos 6737
      pos 6999
    doc 12
      freq 3
      pos 2416
      pos 3598
      pos 4599
    doc 13
      freq 1
      pos 2545
    doc 15
      freq 2
      pos 2199
      pos 2202
  term preferabl
    doc 10
      freq 1
      pos 1631
    doc 12
      freq 1
      pos 3207
    doc 15
      freq 1
      pos 1290
    doc 18
      freq 1
      pos 565
  term preferably
    doc 4
      freq 1
      pos 2704
    doc 10
      freq 2
      pos 2709
      pos 10032
    doc 11
      freq 1
      pos 7068
    doc 12
      freq 1
      pos 8550
  term preferenc
    doc 1
      freq 1
      pos 6709
    doc 13
      freq 1
      pos 2517
    doc 15
      freq 1
      pos 3528
  term preferences
    doc 13
      freq 8
      pos 1014
      pos 2986
      pos 4403
      pos 4421
      pos 4437
      pos 4466
      pos 4577
      pos 6039
    doc 15
      freq 2
      pos 2187
      pos 2193
  term preferred
    doc 1
      freq 8
      pos 6426
      pos 6429
      pos 6496
      pos 6576
      pos 6617
      pos 6682
      pos 9433
      pos 9437
    doc 2
      freq 1
      pos 1547
    doc 12
      freq 2
      pos 4794
      pos 4825
  term prefers
    doc 1
      freq 3
      pos 7017
      pos 7043
      pos 7057
    doc 12
      freq 1
      pos 8804
  term prefix
    doc 0
      freq 14
      pos 568
      pos 844
      pos 3749
      pos 4044
      pos 4275
      pos 9957
      pos 10018
      pos 10215
      pos 10273
      pos 10484
      pos 10568
      pos 10725
      pos 10745
      pos 10775
    doc 4
      freq 1
      pos 2673
    doc 11
      freq 1
      pos 7036
    doc 12
      freq 13
      pos 405
      pos 1416
      pos 1477
      pos 1524
      pos 5329
      pos 5902
      pos 6161
      pos 6167
      pos 6207
      pos 6233
      pos 6314
      pos 6334
      pos 6390
  term prefixes
    doc 0
      freq 4
      pos 9991
      pos 10366
      pos 10762
      pos 15731
    doc 12
      freq 1
      pos 6215
  term pregenerat
    doc 18
      freq 1
      pos 960
  term prematurely
    doc 11
      freq 1
      pos 2343
    doc 12
      freq 2
      pos 333
      pos 3254
  term premis
    doc 12
      freq 1
      pos 5027
  term prepared
    doc 17
      freq 1
      pos 1125
  term prepares
    doc 10
      freq 1
      pos 7052
  term prepend
    doc 3
      freq 1
      pos 2582
    doc 14
      freq 3
      pos 710
      pos 874
      pos 926
  term prepended
    doc 1
      freq 4
      pos 476
      pos 486
      pos 554
      pos 646
    doc 3
      freq 3
      pos 2163
      pos 2190
      pos 2200
    doc 4
      freq 1
      pos 1282
  term prepending
    doc 16
      freq 1
      pos 486
  term prepopulated
    doc 10
      freq 2
      pos 11946
      pos 12028
  term presenc
    doc 1
      freq 2
      pos 2544
      pos 5180
    doc 3
      freq 1
      pos 1388
    doc 10
      freq 3
      pos 775
      pos 10212
      pos 11371
    doc 16
      freq 1
      pos 554
  term present
    doc 0
      freq 4
      pos 3070
      pos 3827
      pos 4327
      pos 11191
    doc 1
      freq 17
      pos 2555
      pos 2564
      pos 2617
      pos 3858
      pos 5518
      pos 5527
      pos 5542
      pos 5853
      pos 5878
      pos 7174
      pos 7182
      pos 7189
      pos 7218
      pos 7241
      pos 7248
      pos 7320
      pos 8197
    doc 3
      freq 7
      pos 2296
      pos 2506
      pos 2774
      pos 3400
      pos 3495
      pos 3547
      pos 3567
    doc 6
      freq 1
      pos 2536
    doc 7
      freq 3
      pos 394
      pos 424
      pos 942
    doc 9
      freq 3
      pos 965
      pos 973
      pos 977
    doc 10
      freq 7
      pos 2258
      pos 2290
      pos 3118
      pos 3861
      pos 5389
      pos 7095
      pos 8832
    doc 11
      freq 2
      pos 4109
      pos 7976
    doc 12
      freq 1
      pos 884
    doc 16
      freq 2
      pos 849
      pos 1612
    doc 17
      freq 1
      pos 1882
    skipList 
      level 0
        skipDoc 11
        skipDocFP 1799433
        impacts 
          impact 
            freq 3
            norm 95
          impact 
            freq 7
            norm 107
          impact 
            freq 17
            norm 113
        impactsEnd 
  term presentation
    doc 6
      freq 1
      pos 2166
    doc 13
      freq 1
      pos 3226
    doc 16
      freq 1
      pos 2229
  term presented
    doc 2
      freq 2
      pos 5773
      pos 5799
    doc 10
      freq 4
      pos 6002
      pos 7772
      pos 8074
      pos 12153
    doc 11
      freq 1
      pos 732
    doc 13
      freq 1
      pos 2999
    doc 17
      freq 1
      pos 471
    doc 18
      freq 1
      pos 418
  term presents
    doc 11
      freq 1
      pos 9313
    doc 12
      freq 2
      pos 67
      pos 511
    doc 13
      freq 1
      pos 6710
    doc 18
      freq 2
      pos 300
      pos 1250
  term preserv
    doc 3
      freq 1
      pos 5226
    doc 7
      freq 1
      pos 1508
  term preserved
    doc 10
      freq 1
      pos 12858
  term preserves
    doc 10
      freq 1
      pos 8442
  term presnick
    doc 16
      freq 2
      pos 2670
      pos 2675
  term pressur
    doc 2
      freq 1
      pos 1177
  term presuhn
    doc 0
      freq 1
      pos 17017
  term presumably
    doc 10
      freq 1
      pos 8120
    doc 13
      freq 1
      pos 972
  term presuppos
    doc 1
      freq 3
      pos 1286
      pos 1319
      pos 1346
  term prevails
    doc 10
      freq 1
      pos 9708
  term prevent
    doc 0
      freq 5
      pos 16235
      pos 16367
      pos 16525
      pos 16545
      pos 16553
    doc 1
      freq 3
      pos 7452
      pos 8103
      pos 8112
    doc 5
      freq 2
      pos 3230
      pos 3488
    doc 6
      freq 2
      pos 1485
      pos 1515
    doc 9
      freq 1
      pos 1566
    doc 10
      freq 10
      pos 3962
      pos 8344
      pos 8452
      pos 8900
      pos 8992
      pos 9637
      pos 9794
      pos 10178
      pos 10200
      pos 12983
    doc 13
      freq 3
      pos 4028
      pos 6124
      pos 6578
    doc 18
      freq 3
      pos 304
      pos 526
      pos 1793
    skipList 
      level 0
        skipDoc 18
        skipDocFP 1801962
        impacts 
          impact 
            freq 1
            norm 95
          impact 
            freq 3
            norm 97
          impact 
            freq 10
            norm 116
        impactsEnd 
  term prevented
    doc 10
      freq 1
      pos 9034
    doc 13
      freq 2
      pos 6524
      pos 6545
  term preventing
    doc 0
      freq 1
      pos 16565
    doc 1
      freq 1
      pos 8584
    doc 10
      freq 1
      pos 9453
    doc 14
      freq 1
      pos 2169
  term prevention
    doc 1
      freq 1
      pos 8026
    doc 4
      freq 1
      pos 4128
    doc 10
      freq 1
      pos 4713
  term prevents
    doc 3
      freq 1
      pos 3353
    doc 10
      freq 1
      pos 8413
  term previous
    doc 2
      freq 1
      pos 6091
    doc 4
      freq 2
      pos 4719
      pos 5456
    doc 6
      freq 1
      pos 1965
    doc 10
      freq 5
      pos 604
      pos 625
      pos 2658
      pos 6937
      pos 10973
    doc 12
      freq 1
      pos 6285
    doc 16
      freq 2
      pos 1708
      pos 1899
    doc 18
      freq 1
      pos 1584
  term previously
    doc 1
      freq 1
      pos 3359
    doc 7
      freq 1
      pos 1336
    doc 10
      freq 2
      pos 2646
      pos 4011
    doc 15
      freq 1
      pos 1507
  term prf
    doc 5
      freq 12
      pos 1212
      pos 1214
      pos 1906
      pos 1923
      pos 2077
      pos 2097
      pos 3926
      pos 3930
      pos 3986
      pos 4041
      pos 4048
      pos 4049
  term pri
    doc 3
      freq 8
      pos 3793
      pos 3879
      pos 3907
      pos 5229
      pos 5468
      pos 5511
      pos 5517
      pos 5671
    doc 13
      freq 3
      pos 6057
      pos 6079
      pos 6108
  term primarily
    doc 13
      freq 1
      pos 1914
  term primary
    doc 10
      freq 2
      pos 826
      pos 9461
  term principal
    doc 15
      freq 1
      pos 3302
  term principals
    doc 0
      freq 1
      pos 16867
  term principl
    doc 15
      freq 1
      pos 2234
  term principles
    doc 3
      freq 1
      pos 5651
  term print
    doc 10
      freq 1
      pos 12416
    doc 11
      freq 1
      pos 9821
  term printabl
    doc 11
      freq 2
      pos 113
      pos 997
    doc 14
      freq 2
      pos 2144
      pos 2931
  term printers
    doc 15
      freq 1
      pos 3360
  term prior
    doc 0
      freq 2
      pos 16749
      pos 16803
    doc 2
      freq 2
      pos 1973
      pos 6254
    doc 5
      freq 1
      pos 3083
    doc 10
      freq 1
      pos 10147
    doc 12
      freq 2
      pos 2602
      pos 5682
    doc 13
      freq 1
      pos 4993
    doc 14
      freq 3
      pos 345
      pos 1976
      pos 1992
  term prioritization
    doc 13
      freq 2
      pos 1772
      pos 2383
  term priority
    doc 0
      freq 3
      pos 2008
      pos 6478
      pos 9299
    doc 2
      freq 1
      pos 4201
    doc 3
      freq 2
      pos 3792
      pos 5687
    doc 15
      freq 1
      pos 976
  term priv
    doc 10
      freq 4
      pos 8044
      pos 8148
      pos 8153
      pos 8174
  term privacy
    doc 0
      freq 1
      pos 16746
    doc 1
      freq 3
      pos 8371
      pos 8675
      pos 8677
    doc 6
      freq 1
      pos 2858
    doc 7
      freq 8
      pos 796
      pos 811
      pos 825
      pos 839
      pos 2206
      pos 2221
      pos 2235
      pos 2249
    doc 10
      freq 12
      pos 264
      pos 7767
      pos 7784
      pos 7799
      pos 7908
      pos 7979
      pos 7987
      pos 8013
      pos 8164
      pos 8181
      pos 8203
      pos 13139
    doc 12
      freq 3
      pos 1334
      pos 5922
      pos 7129
    doc 13
      freq 3
      pos 316
      pos 5772
      pos 6019
  term privat
    doc 1
      freq 2
      pos 611
      pos 4466
    doc 3
      freq 2
      pos 1222
      pos 4705
    doc 4
      freq 9
      pos 789
      pos 792
      pos 818
      pos 821
      pos 841
      pos 5129
      pos 5132
      pos 5143
      pos 5146
    doc 5
      freq 2
      pos 3814
      pos 4030
    doc 10
      freq 24
      pos 1642
      pos 1959
      pos 2137
      pos 2703
      pos 2717
      pos 2880
      pos 2908
      pos 4300
      pos 6012
      pos 6192
      pos 6206
      pos 6244
      pos 6548
      pos 6820
      pos 6830
      pos 6875
      pos 7251
      pos 7830
      pos 7857
      pos 7949
      pos 10553
      pos 10694
      pos 12323
      pos 13294
    doc 12
      freq 3
      pos 6916
      pos 8046
      pos 8061
    doc 17
      freq 2
      pos 1411
      pos 1497
    doc 18
      freq 5
      pos 355
      pos 471
      pos 1666
      pos 1669
      pos 1731
    skipList 
      level 0
        skipDoc 18
        skipDocFP 1806400
        impacts 
          impact 
            freq 5
            norm 97
          impact 
            freq 9
            norm 108
          impact 
            freq 24
            norm 116
        impactsEnd 
  term privileged
    doc 10
      freq 1
      pos 1473
  term privkey
    doc 10
      freq 1
      pos 12321
  term probably
    doc 2
      freq 1
      pos 3939
    doc 10
      freq 1
      pos 652
    doc 12
      freq 2
      pos 3577
      pos 3839
    doc 13
      freq 1
      pos 2354
    doc 15
      freq 1
      pos 2416
  term probing
    doc 6
      freq 1
      pos 941
  term problem
    doc 0
      freq 6
      pos 12685
      pos 12691
      pos 12706
      pos 14299
      pos 14302
      pos 14337
    doc 1
      freq 3
      pos 8302
      pos 8344
      pos 8830
    doc 2
      freq 2
      pos 4224
      pos 4491
    doc 4
      freq 9
      pos 204
      pos 784
      pos 1699
      pos 2487
      pos 3237
      pos 3385
      pos 3415
      pos 3428
      pos 4459
    doc 6
      freq 1
      pos 2500
    doc 10
      freq 4
      pos 1455
      pos 1589
      pos 3105
      pos 3708
    doc 12
      freq 10
      pos 1814
      pos 1862
      pos 4351
      pos 5705
      pos 8597
      pos 8619
      pos 9003
      pos 9091
      pos 9115
      pos 9282
    doc 13
      freq 3
      pos 157
      pos 1075
      pos 1522
    doc 15
      freq 4
      pos 2866
      pos 3123
      pos 3184
      pos 3818
    skipList 
      level 0
        skipDoc 13
        skipDocFP 1808007
        impacts 
          impact 
            freq 1
            norm 101
          impact 
            freq 9
            norm 108
          impact 
            freq 10
            norm 113
        impactsEnd 
  term problematic
    doc 10
      freq 3
      pos 1749
      pos 4388
      pos 7426
    doc 12
      freq 1
      pos 9076
    doc 15
      freq 1
      pos 1322
    doc 17
      freq 2
      pos 1462
      pos 1503
  term problems
    doc 0
      freq 4
      pos 2921
      pos 16240
      pos 16532
      pos 16614
    doc 1
      freq 1
      pos 8214
    doc 2
      freq 2
      pos 1127
      pos 5038
    doc 4
      freq 1
      pos 924
    doc 7
      freq 1
      pos 1737
    doc 9
      freq 2
      pos 1399
      pos 1403
    doc 10
      freq 2
      pos 3768
      pos 10532
    doc 11
      freq 1
      pos 702
    doc 12
      freq 9
      pos 491
      pos 990
      pos 1727
      pos 1745
      pos 1834
      pos 2096
      pos 6546
      pos 6580
      pos 9060
    doc 15
      freq 3
      pos 150
      pos 1133
      pos 2651
    skipList 
      level 0
        skipDoc 11
        skipDocFP 1809373
        impacts 
          impact 
            freq 2
            norm 95
          impact 
            freq 4
            norm 120
        impactsEnd 
  term proc
    doc 5
      freq 1
      pos 4273
  term procedur
    doc 1
      freq 10
      pos 4359
      pos 5480
      pos 5581
      pos 5915
      pos 6523
      pos 7007
      pos 7032
      pos 7089
      pos 7135
      pos 7262
    doc 4
      freq 4
      pos 243
      pos 4745
      pos 4801
      pos 5904
    doc 5
      freq 1
      pos 930
    doc 7
      freq 7
      pos 123
      pos 207
      pos 220
      pos 303
      pos 1457
      pos 1535
      pos 2735
    doc 9
      freq 1
      pos 1235
    doc 12
      freq 1
      pos 4088
  term procedures
    doc 0
      freq 1
      pos 17405
    doc 1
      freq 18
      pos 183
      pos 285
      pos 309
      pos 348
      pos 417
      pos 808
      pos 944
      pos 1903
      pos 2575
      pos 4320
      pos 4661
      pos 4863
      pos 4914
      pos 5001
      pos 5607
      pos 7094
      pos 9413
      pos 9786
    doc 2
      freq 8
      pos 92
      pos 309
      pos 391
      pos 529
      pos 698
      pos 2256
      pos 2886
      pos 6583
    doc 3
      freq 11
      pos 147
      pos 220
      pos 495
      pos 521
      pos 668
      pos 700
      pos 1707
      pos 1855
      pos 2127
      pos 2225
      pos 6135
    doc 4
      freq 3
      pos 340
      pos 353
      pos 6290
    doc 5
      freq 1
      pos 4620
    doc 6
      freq 1
      pos 3420
    doc 7
      freq 3
      pos 808
      pos 2218
      pos 3125
    doc 8
      freq 2
      pos 384
      pos 2342
    doc 9
      freq 1
      pos 1987
    doc 10
      freq 9
      pos 2414
      pos 3126
      pos 4113
      pos 4205
      pos 10478
      pos 10602
      pos 10756
      pos 10776
      pos 13648
    doc 11
      freq 1
      pos 10809
    doc 12
      freq 7
      pos 422
      pos 6569
      pos 6586
      pos 6841
      pos 7394
      pos 7981
      pos 9659
    doc 13
      freq 1
      pos 7274
    doc 14
      freq 1
      pos 5740
    doc 15
      freq 1
      pos 4259
    doc 16
      freq 1
      pos 2870
    doc 17
      freq 6
      pos 194
      pos 1483
      pos 1566
      pos 2017
      pos 2026
      pos 2594
    doc 18
      freq 1
      pos 2382
    skipList 
      level 0
        skipDoc 7
        skipDocFP 1810799
        impacts 
          impact 
            freq 3
            norm 100
          impact 
            freq 11
            norm 107
          impact 
            freq 18
            norm 113
        impactsEnd 
        skipDoc 15
        skipDocFP 1811654
        impacts 
          impact 
            freq 1
            norm 95
          impact 
            freq 2
            norm 97
          impact 
            freq 7
            norm 113
          impact 
            freq 9
            norm 116
        impactsEnd 
  term procedures.pdf
    doc 2
      freq 1
      pos 2895
  term proceed
    doc 1
      freq 1
      pos 6640
    doc 14
      freq 12
      pos 738
      pos 769
      pos 802
      pos 868
      pos 943
      pos 993
      pos 1059
      pos 1429
      pos 1460
      pos 1605
      pos 1645
      pos 1711
  term proceeded
    doc 2
      freq 1
      pos 5224
  term proceeding
    doc 18
      freq 1
      pos 849
  term process
    doc 0
      freq 2
      pos 5336
      pos 6759
    doc 1
      freq 2
      pos 1663
      pos 5923
    doc 2
      freq 15
      pos 847
      pos 1140
      pos 1169
      pos 1259
      pos 1303
      pos 1321
      pos 1738
      pos 1813
      pos 2062
      pos 2070
      pos 2090
      pos 4526
      pos 5385
      pos 5458
      pos 5513
    doc 3
      freq 2
      pos 1180
      pos 3544
    doc 4
      freq 14
      pos 1052
      pos 1397
      pos 1488
      pos 1517
      pos 2741
      pos 2745
      pos 2902
      pos 2987
      pos 2991
      pos 3223
      pos 3227
      pos 3526
      pos 3530
      pos 3973
    doc 7
      freq 3
      pos 1331
      pos 1436
      pos 1809
    doc 8
      freq 2
      pos 254
      pos 393
    doc 10
      freq 7
      pos 2480
      pos 3654
      pos 3846
      pos 4158
      pos 9925
      pos 10423
      pos 10505
    doc 11
      freq 4
      pos 3593
      pos 4822
      pos 7819
      pos 8585
    doc 12
      freq 7
      pos 3241
      pos 5674
      pos 5711
      pos 5751
      pos 6149
      pos 8899
      pos 8968
    doc 13
      freq 1
      pos 1323
    doc 16
      freq 1
      pos 1261
    doc 17
      freq 1
      pos 623
    doc 18
      freq 1
      pos 271
    skipList 
      level 0
        skipDoc 10
        skipDocFP 1813419
        impacts 
          impact 
            freq 2
            norm 97
          impact 
            freq 3
            norm 100
          impact 
            freq 15
            norm 108
        impactsEnd 
  term processed
    doc 3
      freq 1
      pos 2299
    doc 10
      freq 1
      pos 3262
  term processes
    doc 2
      freq 3
      pos 519
      pos 1801
      pos 2235
    doc 4
      freq 3
      pos 3709
      pos 3988
      pos 4576
    doc 8
      freq 1
      pos 205
    doc 10
      freq 2
      pos 4067
      pos 10371
  term processing
    doc 0
      freq 2
      pos 5670
      pos 16921
    doc 1
      freq 4
      pos 2038
      pos 4554
      pos 6116
      pos 7662
    doc 2
      freq 1
      pos 638
    doc 3
      freq 10
      pos 245
      pos 524
      pos 969
      pos 974
      pos 1357
      pos 3021
      pos 3087
      pos 3126
      pos 3735
      pos 3775
    doc 4
      freq 9
      pos 178
      pos 487
      pos 1345
      pos 1354
      pos 1550
      pos 3380
      pos 3401
      pos 4663
      pos 5737
    doc 5
      freq 1
      pos 2964
    doc 11
      freq 5
      pos 5593
      pos 5759
      pos 6082
      pos 7967
      pos 8424
    doc 13
      freq 1
      pos 2230
    doc 14
      freq 1
      pos 643
    doc 15
      freq 1
      pos 153
    doc 16
      freq 1
      pos 359
    doc 17
      freq 1
      pos 1037
    skipList 
      level 0
        skipDoc 13
        skipDocFP 1815317
        impacts 
          impact 
            freq 1
            norm 104
          impact 
            freq 10
            norm 107
        impactsEnd 
  term produc
    doc 2
      freq 1
      pos 5940
    doc 17
      freq 1
      pos 1511
    doc 18
      freq 3
      pos 984
      pos 1372
      pos 1871
  term produced
    doc 2
      freq 1
      pos 5607
    doc 11
      freq 1
      pos 3942
    doc 13
      freq 1
      pos 1582
    doc 18
      freq 1
      pos 760
  term produces
    doc 1
      freq 1
      pos 8555
  term production
    doc 6
      freq 1
      pos 835
    doc 7
      freq 1
      pos 251
    doc 11
      freq 2
      pos 1712
      pos 1772
  term productions
    doc 11
      freq 1
      pos 1785
  term profil
    doc 10
      freq 1
      pos 13248
    doc 12
      freq 1
      pos 5910
    doc 17
      freq 2
      pos 2068
      pos 2083
  term program
    doc 2
      freq 2
      pos 755
      pos 2295
    doc 13
      freq 7
      pos 206
      pos 563
      pos 583
      pos 626
      pos 2872
      pos 2955
      pos 3021
  term programmed
    doc 12
      freq 1
      pos 3743
  term programming
    doc 13
      freq 1
      pos 3083
  term programs
    doc 13
      freq 4
      pos 2908
      pos 2913
      pos 2965
      pos 3029
  term progress
    doc 0
      freq 1
      pos 2164
    doc 1
      freq 5
      pos 8995
      pos 9012
      pos 9047
      pos 9070
      pos 9096
    doc 2
      freq 17
      pos 764
      pos 795
      pos 860
      pos 956
      pos 1972
      pos 1988
      pos 2017
      pos 2098
      pos 2334
      pos 2347
      pos 2476
      pos 2815
      pos 2843
      pos 4061
      pos 4632
      pos 5356
      pos 5693
    doc 3
      freq 5
      pos 4548
      pos 4606
      pos 4639
      pos 4658
      pos 4678
    doc 4
      freq 1
      pos 5448
    doc 5
      freq 2
      pos 4252
      pos 4393
    doc 6
      freq 1
      pos 303
    doc 7
      freq 1
      pos 1424
    doc 8
      freq 11
      pos 1827
      pos 1842
      pos 1861
      pos 1885
      pos 1902
      pos 1922
      pos 1959
      pos 1983
      pos 2035
      pos 2051
      pos 2096
    doc 10
      freq 1
      pos 13376
    doc 11
      freq 2
      pos 5058
      pos 9711
    doc 12
      freq 12
      pos 7673
      pos 7695
      pos 7723
      pos 7739
      pos 7755
      pos 7768
      pos 7785
      pos 7807
      pos 7821
      pos 7839
      pos 7856
      pos 7875
    doc 13
      freq 1
      pos 6825
    doc 14
      freq 1
      pos 5502
    skipList 
      level 0
        skipDoc 7
        skipDocFP 1817530
        impacts 
          impact 
            freq 1
            norm 100
          impact 
            freq 2
            norm 104
          impact 
            freq 5
            norm 107
          impact 
            freq 17
            norm 108
        impactsEnd 
  term progresses
    doc 6
      freq 1
      pos 1594
  term progression
    doc 15
      freq 2
      pos 3773
      pos 3789
  term progressively
    doc 13
      freq 1
      pos 2251
  term prohibited
    doc 4
      freq 1
      pos 2178
  term prohibiting
    doc 4
      freq 1
      pos 5652
  term prohibition
    doc 4
      freq 1
      pos 2349
  term project
    doc 2
      freq 2
      pos 1004
      pos 2877
    doc 10
      freq 1
      pos 2888
    doc 12
      freq 1
      pos 7600
    doc 13
      freq 1
      pos 6807
    doc 15
      freq 1
      pos 3889
  term promising
    doc 10
      freq 1
      pos 11135
  term promot
    doc 17
      freq 1
      pos 935
  term promoted
    doc 15
      freq 1
      pos 3066
  term promotional
    doc 13
      freq 1
      pos 3613
  term prompt
    doc 7
      freq 1
      pos 2873
  term prompted
    doc 13
      freq 1
      pos 3045
  term proof
    doc 10
      freq 1
      pos 943
    doc 11
      freq 1
      pos 6850
  term propagat
    doc 0
      freq 1
      pos 13874
    doc 11
      freq 1
      pos 6559
  term propagating
    doc 12
      freq 1
      pos 9005
  term propagation
    doc 0
      freq 3
      pos 10844
      pos 11384
      pos 16567
  term proper
    doc 0
      freq 1
      pos 16150
    doc 3
      freq 4
      pos 2184
      pos 2196
      pos 2214
      pos 2257
    doc 5
      freq 1
      pos 1094
    doc 10
      freq 2
      pos 7608
      pos 9013
    doc 11
      freq 1
      pos 7680
    doc 12
      freq 2
      pos 1713
      pos 5204
    doc 17
      freq 1
      pos 1747
  term properly
    doc 0
      freq 1
      pos 16856
    doc 3
      freq 1
      pos 1740
    doc 6
      freq 1
      pos 406
    doc 11
      freq 1
      pos 3725
    doc 12
      freq 3
      pos 1798
      pos 3744
      pos 5149
    doc 17
      freq 1
      pos 1769
  term properties
    doc 5
      freq 3
      pos 2745
      pos 3521
      pos 3687
    doc 9
      freq 1
      pos 1119
    doc 10
      freq 4
      pos 3287
      pos 5291
      pos 8321
      pos 8342
    doc 11
      freq 1
      pos 2443
    doc 12
      freq 3
      pos 2052
      pos 6144
      pos 7932
    doc 13
      freq 8
      pos 263
      pos 1127
      pos 1941
      pos 2892
      pos 3321
      pos 3868
      pos 3894
      pos 4605
  term property
    doc 0
      freq 2
      pos 17333
      pos 17347
    doc 1
      freq 2
      pos 9714
      pos 9728
    doc 2
      freq 2
      pos 6511
      pos 6525
    doc 3
      freq 2
      pos 6063
      pos 6077
    doc 4
      freq 2
      pos 6218
      pos 6232
    doc 5
      freq 2
      pos 4548
      pos 4562
    doc 6
      freq 2
      pos 3348
      pos 3362
    doc 7
      freq 2
      pos 3053
      pos 3067
    doc 8
      freq 2
      pos 2270
      pos 2284
    doc 9
      freq 2
      pos 1915
      pos 1929
    doc 10
      freq 2
      pos 13576
      pos 13590
    doc 11
      freq 2
      pos 10737
      pos 10751
    doc 12
      freq 3
      pos 893
      pos 9587
      pos 9601
    doc 13
      freq 3
      pos 5642
      pos 7202
      pos 7216
    doc 14
      freq 2
      pos 5668
      pos 5682
    doc 15
      freq 2
      pos 4187
      pos 4201
    doc 16
      freq 2
      pos 2798
      pos 2812
    doc 17
      freq 2
      pos 2522
      pos 2536
    doc 18
      freq 2
      pos 2310
      pos 2324
    skipList 
      level 0
        skipDoc 7
        skipDocFP 1821469
        impacts 
          impact 
            freq 2
            norm 100
        impactsEnd 
        skipDoc 15
        skipDocFP 1821895
        impacts 
          impact 
            freq 2
            norm 95
          impact 
            freq 3
            norm 109
        impactsEnd 
  term proportion
    doc 11
      freq 1
      pos 2812
  term propos
    doc 15
      freq 1
      pos 3826
  term proposals
    doc 14
      freq 1
      pos 287
  term proposed
    doc 0
      freq 1
      pos 6693
    doc 2
      freq 4
      pos 989
      pos 1001
      pos 1030
      pos 1034
    doc 5
      freq 1
      pos 830
    doc 6
      freq 11
      pos 20
      pos 290
      pos 743
      pos 1133
      pos 1614
      pos 2029
      pos 2343
      pos 2759
      pos 2897
      pos 3036
      pos 3226
    doc 7
      freq 6
      pos 82
      pos 104
      pos 174
      pos 323
      pos 485
      pos 1610
    doc 15
      freq 1
      pos 1770
  term proposes
    doc 10
      freq 1
      pos 1257
  term proprietary
    doc 0
      freq 2
      pos 17459
      pos 17501
    doc 1
      freq 2
      pos 9840
      pos 9882
    doc 2
      freq 3
      pos 4170
      pos 6637
      pos 6679
    doc 3
      freq 2
      pos 6189
      pos 6231
    doc 4
      freq 2
      pos 6344
      pos 6386
    doc 5
      freq 2
      pos 4674
      pos 4716
    doc 6
      freq 2
      pos 3474
      pos 3516
    doc 7
      freq 2
      pos 3179
      pos 3221
    doc 8
      freq 12
      pos 276
      pos 281
      pos 562
      pos 597
      pos 893
      pos 975
      pos 1218
      pos 1269
      pos 1399
      pos 1464
      pos 2396
      pos 2438
    doc 9
      freq 2
      pos 2041
      pos 2083
    doc 10
      freq 2
      pos 13702
      pos 13744
    doc 11
      freq 2
      pos 10863
      pos 10905
    doc 12
      freq 2
      pos 9713
      pos 9755
    doc 13
      freq 2
      pos 7328
      pos 7370
    doc 14
      freq 2
      pos 5794
      pos 5836
    doc 15
      freq 2
      pos 4313
      pos 4355
    doc 16
      freq 2
      pos 2924
      pos 2966
    doc 17
      freq 2
      pos 2648
      pos 2690
    doc 18
      freq 2
      pos 2436
      pos 2478
    skipList 
      level 0
        skipDoc 7
        skipDocFP 1823627
        impacts 
          impact 
            freq 2
            norm 100
          impact 
            freq 3
            norm 108
        impactsEnd 
        skipDoc 15
        skipDocFP 1824068
        impacts 
          impact 
            freq 2
            norm 95
          impact 
            freq 12
            norm 97
        impactsEnd 
  term prot
    doc 5
      freq 8
      pos 1612
      pos 1683
      pos 1709
      pos 3712
      pos 3834
      pos 3836
      pos 3853
      pos 3860
  term protect
    doc 5
      freq 1
      pos 175
    doc 10
      freq 5
      pos 5854
      pos 9089
      pos 9258
      pos 9283
      pos 9416
    doc 11
      freq 1
      pos 8437
    doc 13
      freq 1
      pos 5770
    doc 17
      freq 1
      pos 1409
  term protected
    doc 4
      freq 1
      pos 4385
    doc 5
      freq 5
      pos 533
      pos 820
      pos 3140
      pos 3228
      pos 3376
    doc 9
      freq 1
      pos 1319
    doc 10
      freq 1
      pos 8005
    doc 13
      freq 3
      pos 5797
      pos 6171
      pos 6553
  term protecting
    doc 4
      freq 1
      pos 4643
    doc 9
      freq 1
      pos 162
    doc 10
      freq 1
      pos 13006
  term protection
    doc 0
      freq 1
      pos 16151
    doc 1
      freq 1
      pos 8719
    doc 4
      freq 7
      pos 4159
      pos 4210
      pos 4237
      pos 4260
      pos 4295
      pos 4300
      pos 4315
    doc 5
      freq 8
      pos 1038
      pos 2153
      pos 2943
      pos 3021
      pos 3143
      pos 3402
      pos 3628
      pos 3683
    doc 9
      freq 5
      pos 817
      pos 1127
      pos 1264
      pos 1289
      pos 1384
    doc 10
      freq 10
      pos 4349
      pos 8259
      pos 8482
      pos 8815
      pos 9743
      pos 10136
      pos 10221
      pos 10230
      pos 11357
      pos 12999
    doc 13
      freq 1
      pos 6048
  term protects
    doc 4
      freq 2
      pos 4279
      pos 4347
  term protocol
    doc 0
      freq 47
      pos 39
      pos 61
      pos 73
      pos 126
      pos 248
      pos 318
      pos 476
      pos 543
      pos 607
      pos 718
      pos 742
      pos 759
      pos 854
      pos 879
      pos 1134
      pos 1182
      pos 1335
      pos 1364
      pos 1463
      pos 1644
      pos 1664
      pos 2123
      pos 2141
      pos 2305
      pos 3122
      pos 5674
      pos 5928
      pos 8284
      pos 8313
      pos 9793
      pos 9799
      pos 9868
      pos 9926
      pos 9967
      pos 10851
      pos 10881
      pos 10914
      pos 11391
      pos 12487
      pos 13618
      pos 15688
      pos 15877
      pos 15889
      pos 16053
      pos 16896
      pos 16903
      pos 17029
    doc 1
      freq 29
      pos 43
      pos 56
      pos 78
      pos 90
      pos 130
      pos 169
      pos 181
      pos 451
      pos 737
      pos 742
      pos 844
      pos 1108
      pos 1809
      pos 1818
      pos 1876
      pos 1891
      pos 1938
      pos 1959
      pos 3079
      pos 3119
      pos 3478
      pos 4451
      pos 7066
      pos 7923
      pos 8018
      pos 8059
      pos 8535
      pos 8545
      pos 8750
    doc 2
      freq 21
      pos 76
      pos 289
      pos 1236
      pos 1886
      pos 2174
      pos 2317
      pos 2414
      pos 2808
      pos 2963
      pos 2980
      pos 3059
      pos 3083
      pos 3152
      pos 3277
      pos 3293
      pos 3342
      pos 3692
      pos 3697
      pos 4154
      pos 6065
      pos 6139
    doc 3
      freq 15
      pos 50
      pos 72
      pos 84
      pos 110
      pos 351
      pos 361
      pos 398
      pos 748
      pos 1560
      pos 1735
      pos 3815
      pos 3840
      pos 4219
      pos 4378
      pos 4724
    doc 4
      freq 31
      pos 31
      pos 36
      pos 52
      pos 74
      pos 86
      pos 119
      pos 126
      pos 129
      pos 284
      pos 293
      pos 308
      pos 511
      pos 1050
      pos 1475
      pos 1492
      pos 1534
      pos 1576
      pos 2579
      pos 2588
      pos 4030
      pos 4055
      pos 4909
      pos 5183
      pos 5219
      pos 5236
      pos 5241
      pos 5318
      pos 5336
      pos 5377
      pos 5433
      pos 5888
    doc 5
      freq 39
      pos 36
      pos 58
      pos 70
      pos 94
      pos 105
      pos 160
      pos 203
      pos 597
      pos 1559
      pos 1692
      pos 1735
      pos 1761
      pos 1781
      pos 2245
      pos 2458
      pos 2821
      pos 2847
      pos 2895
      pos 2903
      pos 2914
      pos 2959
      pos 3037
      pos 3064
      pos 3097
      pos 3109
      pos 3274
      pos 3418
      pos 3439
      pos 3516
      pos 3543
      pos 3551
      pos 3718
      pos 3723
      pos 3846
      pos 4232
      pos 4292
      pos 4310
      pos 4336
      pos 4370
    doc 6
      freq 8
      pos 784
      pos 822
      pos 826
      pos 879
      pos 2664
      pos 2883
      pos 3053
      pos 3075
    doc 7
      freq 35
      pos 757
      pos 773
      pos 885
      pos 891
      pos 907
      pos 1001
      pos 1035
      pos 1084
      pos 1093
      pos 1226
      pos 1909
      pos 2015
      pos 2094
      pos 2096
      pos 2119
      pos 2127
      pos 2163
      pos 2167
      pos 2294
      pos 2300
      pos 2317
      pos 2330
      pos 2336
      pos 2349
      pos 2355
      pos 2371
      pos 2489
      pos 2580
      pos 2660
      pos 2677
      pos 2686
      pos 2737
      pos 2794
      pos 2821
      pos 2838
    doc 8
      freq 3
      pos 77
      pos 1700
      pos 1806
    doc 9
      freq 3
      pos 38
      pos 60
      pos 72
    doc 10
      freq 14
      pos 28
      pos 41
      pos 63
      pos 75
      pos 99
      pos 420
      pos 9092
      pos 11347
      pos 13111
      pos 13145
      pos 13159
      pos 13173
      pos 13300
      pos 13394
    doc 11
      freq 9
      pos 33
      pos 83
      pos 361
      pos 588
      pos 602
      pos 784
      pos 6639
      pos 9650
      pos 9668
    doc 12
      freq 16
      pos 997
      pos 1051
      pos 1062
      pos 3638
      pos 3914
      pos 7104
      pos 7188
      pos 7210
      pos 7251
      pos 7290
      pos 7305
      pos 7480
      pos 9002
      pos 9243
      pos 9317
      pos 9411
    doc 13
      freq 25
      pos 427
      pos 448
      pos 1410
      pos 1438
      pos 1440
      pos 1491
      pos 1504
      pos 1586
      pos 1591
      pos 1597
      pos 1708
      pos 1761
      pos 2331
      pos 2809
      pos 2818
      pos 3701
      pos 3847
      pos 4050
      pos 5050
      pos 5142
      pos 6766
      pos 6781
      pos 6849
      pos 6899
      pos 6911
    doc 14
      freq 2
      pos 32
      pos 2650
    doc 15
      freq 21
      pos 28
      pos 104
      pos 241
      pos 321
      pos 1414
      pos 1425
      pos 1481
      pos 1724
      pos 2091
      pos 2212
      pos 2248
      pos 2369
      pos 2864
      pos 2901
      pos 3299
      pos 3493
      pos 3829
      pos 3904
      pos 3954
      pos 3969
      pos 3992
    doc 16
      freq 10
      pos 22
      pos 37
      pos 59
      pos 71
      pos 95
      pos 184
      pos 1616
      pos 2528
      pos 2551
      pos 2597
    doc 17
      freq 3
      pos 34
      pos 56
      pos 68
    doc 18
      freq 4
      pos 43
      pos 65
      pos 77
      pos 2115
    skipList 
      level 0
        skipDoc 7
        skipDocFP 1826851
        impacts 
          impact 
            freq 35
            norm 100
          impact 
            freq 39
            norm 104
          impact 
            freq 47
            norm 120
        impactsEnd 
        skipDoc 15
        skipDocFP 1830346
        impacts 
          impact 
            freq 3
            norm 95
          impact 
            freq 21
            norm 104
          impact 
            freq 25
            norm 109
        impactsEnd 
  term protocols
    doc 0
      freq 9
      pos 105
      pos 804
      pos 1681
      pos 2964
      pos 9806
      pos 9838
      pos 12615
      pos 14096
      pos 14119
    doc 3
      freq 1
      pos 2274
    doc 4
      freq 2
      pos 4587
      pos 6019
    doc 5
      freq 3
      pos 774
      pos 2162
      pos 3643
    doc 6
      freq 2
      pos 141
      pos 585
    doc 7
      freq 5
      pos 1189
      pos 1200
      pos 1248
      pos 2311
      pos 2744
    doc 8
      freq 3
      pos 80
      pos 207
      pos 1688
    doc 10
      freq 1
      pos 13266
    doc 12
      freq 3
      pos 600
      pos 2727
      pos 4396
    doc 13
      freq 11
      pos 82
      pos 110
      pos 1166
      pos 1544
      pos 1578
      pos 1639
      pos 3767
      pos 3951
      pos 5079
      pos 5111
      pos 5164
    doc 15
      freq 8
      pos 85
      pos 364
      pos 1151
      pos 1280
      pos 1879
      pos 2460
      pos 3256
      pos 3383
    skipList 
      level 0
        skipDoc 10
        skipDocFP 1832770
        impacts 
          impact 
            freq 3
            norm 97
          impact 
            freq 5
            norm 100
          impact 
            freq 9
            norm 120
        impactsEnd 
  term proulx
    doc 6
      freq 1
      pos 3124
  term prove
    doc 10
      freq 3
      pos 1076
      pos 1091
      pos 9307
    doc 18
      freq 1
      pos 747
  term proved
    doc 2
      freq 1
      pos 2079
  term proven
    doc 2
      freq 1
      pos 1978
    doc 18
      freq 1
      pos 611
  term proves
    doc 10
      freq 1
      pos 961
    doc 18
      freq 2
      pos 1535
      pos 1546
  term provid
    doc 0
      freq 5
      pos 614
      pos 1769
      pos 1813
      pos 5222
      pos 12003
    doc 1
      freq 6
      pos 147
      pos 1893
      pos 2774
      pos 8038
      pos 8674
      pos 8717
    doc 2
      freq 4
      pos 942
      pos 3855
      pos 5848
      pos 6142
    doc 3
      freq 6
      pos 153
      pos 503
      pos 2959
      pos 2975
      pos 3721
      pos 5313
    doc 4
      freq 1
      pos 4258
    doc 5
      freq 10
      pos 551
      pos 703
      pos 858
      pos 1021
      pos 2149
      pos 3015
      pos 3088
      pos 3101
      pos 3150
      pos 3518
    doc 6
      freq 3
      pos 315
      pos 1373
      pos 2595
    doc 7
      freq 3
      pos 711
      pos 1667
      pos 2035
    doc 9
      freq 2
      pos 1203
      pos 1383
    doc 10
      freq 22
      pos 653
      pos 863
      pos 1062
      pos 1615
      pos 3248
      pos 3612
      pos 4347
      pos 4711
      pos 5687
      pos 7401
      pos 7563
      pos 7729
      pos 7811
      pos 8257
      pos 8477
      pos 8813
      pos 8824
      pos 9300
      pos 9392
      pos 10851
      pos 12875
      pos 12996
    doc 12
      freq 4
      pos 1574
      pos 1704
      pos 2235
      pos 5370
    doc 13
      freq 13
      pos 643
      pos 1000
      pos 1507
      pos 2049
      pos 2767
      pos 3365
      pos 3850
      pos 3924
      pos 4024
      pos 4539
      pos 5098
      pos 5116
      pos 5696
    doc 14
      freq 1
      pos 103
    doc 15
      freq 3
      pos 1957
      pos 2107
      pos 2919
    doc 16
      freq 1
      pos 316
    skipList 
      level 0
        skipDoc 7
        skipDocFP 1834454
        impacts 
          impact 
            freq 3
            norm 100
          impact 
            freq 10
            norm 104
        impactsEnd 
  term provided
    doc 0
      freq 4
      pos 16715
      pos 16726
      pos 17266
      pos 17534
    doc 1
      freq 4
      pos 3010
      pos 6274
      pos 9647
      pos 9915
    doc 2
      freq 6
      pos 741
      pos 895
      pos 2158
      pos 3596
      pos 6444
      pos 6712
    doc 3
      freq 4
      pos 1550
      pos 3240
      pos 5996
      pos 6264
    doc 4
      freq 5
      pos 4301
      pos 4316
      pos 5508
      pos 6151
      pos 6419
    doc 5
      freq 16
      pos 813
      pos 902
      pos 917
      pos 1041
      pos 1092
      pos 3076
      pos 3186
      pos 3213
      pos 3252
      pos 3257
      pos 3397
      pos 3496
      pos 3631
      pos 3708
      pos 4481
      pos 4749
    doc 6
      freq 2
      pos 3281
      pos 3549
    doc 7
      freq 3
      pos 392
      pos 2986
      pos 3254
    doc 8
      freq 7
      pos 424
      pos 617
      pos 995
      pos 1289
      pos 1484
      pos 2203
      pos 2471
    doc 9
      freq 3
      pos 1274
      pos 1848
      pos 2116
    doc 10
      freq 17
      pos 2030
      pos 3363
      pos 3762
      pos 3840
      pos 3999
      pos 4613
      pos 4691
      pos 5143
      pos 5384
      pos 8060
      pos 10018
      pos 10194
      pos 10947
      pos 11014
      pos 12141
      pos 13509
      pos 13777
    doc 11
      freq 3
      pos 9548
      pos 10670
      pos 10938
    doc 12
      freq 8
      pos 3117
      pos 3781
      pos 6773
      pos 6816
      pos 6826
      pos 8039
      pos 9520
      pos 9788
    doc 13
      freq 5
      pos 2555
      pos 4208
      pos 6637
      pos 7135
      pos 7403
    doc 14
      freq 2
      pos 5601
      pos 5869
    doc 15
      freq 2
      pos 4120
      pos 4388
    doc 16
      freq 4
      pos 1208
      pos 2280
      pos 2731
      pos 2999
    doc 17
      freq 3
      pos 1893
      pos 2455
      pos 2723
    doc 18
      freq 2
      pos 2243
      pos 2511
    skipList 
      level 0
        skipDoc 7
        skipDocFP 1836299
        impacts 
          impact 
            freq 3
            norm 100
          impact 
            freq 16
            norm 104
        impactsEnd 
        skipDoc 15
        skipDocFP 1837142
        impacts 
          impact 
            freq 3
            norm 95
          impact 
            freq 7
            norm 97
          impact 
            freq 8
            norm 113
          impact 
            freq 17
            norm 116
        impactsEnd 
  term provider
    doc 1
      freq 2
      pos 1036
      pos 1039
    doc 3
      freq 10
      pos 526
      pos 611
      pos 614
      pos 1273
      pos 2370
      pos 2381
      pos 2399
      pos 4047
      pos 4702
      pos 5647
    doc 13
      freq 4
      pos 2516
      pos 3392
      pos 3410
      pos 3433
  term providers
    doc 1
      freq 1
      pos 8153
    doc 3
      freq 1
      pos 121
    doc 6
      freq 2
      pos 438
      pos 887
    doc 10
      freq 1
      pos 10937
    doc 13
      freq 2
      pos 975
      pos 2617
  term provides
    doc 0
      freq 8
      pos 551
      pos 1720
      pos 1761
      pos 4027
      pos 9517
      pos 11694
      pos 11702
      pos 11741
    doc 1
      freq 2
      pos 8206
      pos 8651
    doc 2
      freq 1
      pos 28
    doc 3
      freq 4
      pos 933
      pos 3286
      pos 3479
      pos 3519
    doc 4
      freq 2
      pos 4235
      pos 4294
    doc 5
      freq 5
      pos 95
      pos 475
      pos 1157
      pos 1196
      pos 3124
    doc 6
      freq 9
      pos 31
      pos 225
      pos 654
      pos 892
      pos 916
      pos 1008
      pos 1452
      pos 1554
      pos 2273
    doc 7
      freq 1
      pos 42
    doc 10
      freq 10
      pos 406
      pos 667
      pos 1779
      pos 3499
      pos 3727
      pos 8220
      pos 8339
      pos 8388
      pos 9071
      pos 9384
    doc 11
      freq 2
      pos 44
      pos 7043
    doc 12
      freq 3
      pos 34
      pos 2153
      pos 6952
    doc 13
      freq 7
      pos 43
      pos 1073
      pos 1111
      pos 2103
      pos 3693
      pos 3761
      pos 4326
    doc 15
      freq 2
      pos 42
      pos 2066
    skipList 
      level 0
        skipDoc 7
        skipDocFP 1839366
        impacts 
          impact 
            freq 1
            norm 100
          impact 
            freq 9
            norm 101
        impactsEnd 
  term providing
    doc 0
      freq 1
      pos 16905
    doc 2
      freq 1
      pos 5800
    doc 5
      freq 1
      pos 3646
    doc 6
      freq 1
      pos 368
    doc 9
      freq 1
      pos 1287
    doc 10
      freq 7
      pos 1125
      pos 1580
      pos 2711
      pos 4364
      pos 7682
      pos 8399
      pos 9161
    doc 11
      freq 1
      pos 7033
    doc 12
      freq 1
      pos 689
    doc 13
      freq 2
      pos 4618
      pos 5630
    doc 14
      freq 1
      pos 2615
    skipList 
      level 0
        skipDoc 12
        skipDocFP 1840731
        impacts 
          impact 
            freq 1
            norm 95
          impact 
            freq 7
            norm 116
        impactsEnd 
  term proving
    doc 10
      freq 1
      pos 1221
    doc 18
      freq 3
      pos 199
      pos 720
      pos 1948
  term provision
    doc 10
      freq 1
      pos 2697
    doc 15
      freq 1
      pos 3287
  term provisioned
    doc 1
      freq 3
      pos 1927
      pos 2404
      pos 2922
    doc 3
      freq 1
      pos 4703
  term provisioning
    doc 1
      freq 5
      pos 1952
      pos 2185
      pos 3327
      pos 3585
      pos 4470
    doc 2
      freq 1
      pos 3317
    doc 8
      freq 1
      pos 2088
    doc 12
      freq 5
      pos 102
      pos 249
      pos 674
      pos 1955
      pos 6756
  term proxies
    doc 11
      freq 4
      pos 1419
      pos 6846
      pos 7590
      pos 8445
  term proxy
    doc 10
      freq 39
      pos 221
      pos 976
      pos 1364
      pos 1374
      pos 1612
      pos 1803
      pos 1846
      pos 1898
      pos 1953
      pos 1997
      pos 2120
      pos 2172
      pos 2423
      pos 2582
      pos 2602
      pos 2631
      pos 2771
      pos 2809
      pos 2853
      pos 2942
      pos 2986
      pos 4383
      pos 4548
      pos 4677
      pos 4683
      pos 4696
      pos 4721
      pos 4745
      pos 5786
      pos 5816
      pos 6313
      pos 6952
      pos 7792
      pos 9235
      pos 10860
      pos 11153
      pos 12872
      pos 12890
      pos 12935
    doc 11
      freq 16
      pos 431
      pos 1860
      pos 1862
      pos 1870
      pos 2511
      pos 3296
      pos 5895
      pos 6555
      pos 7673
      pos 7684
      pos 7716
      pos 7755
      pos 7814
      pos 7922
      pos 8420
      pos 8569
  term pryhvn9yc6u
    doc 10
      freq 2
      pos 6564
      pos 6657
  term psavol
    doc 12
      freq 1
      pos 9461
  term pseud
    doc 0
      freq 2
      pos 14439
      pos 14605
    doc 1
      freq 1
      pos 9153
    doc 3
      freq 5
      pos 4520
      pos 4540
      pos 4578
      pos 4598
      pos 4669
    doc 4
      freq 3
      pos 1285
      pos 1304
      pos 1312
    doc 5
      freq 3
      pos 3927
      pos 3941
      pos 3964
    doc 8
      freq 2
      pos 87
      pos 1818
    doc 14
      freq 1
      pos 1956
  term pseudonod
    doc 0
      freq 3
      pos 1523
      pos 1554
      pos 14086
  term pseudowir
    doc 1
      freq 57
      pos 35
      pos 224
      pos 290
      pos 306
      pos 467
      pos 482
      pos 493
      pos 504
      pos 516
      pos 529
      pos 638
      pos 779
      pos 794
      pos 811
      pos 820
      pos 848
      pos 866
      pos 884
      pos 1015
      pos 1086
      pos 1188
      pos 1415
      pos 1431
      pos 1444
      pos 1460
      pos 1839
      pos 1925
      pos 1993
      pos 2131
      pos 2159
      pos 2400
      pos 2413
      pos 2525
      pos 2810
      pos 2839
      pos 2857
      pos 2880
      pos 3069
      pos 3085
      pos 3095
      pos 3313
      pos 3323
      pos 3363
      pos 3378
      pos 3462
      pos 3476
      pos 3573
      pos 4805
      pos 4852
      pos 5604
      pos 5673
      pos 5908
      pos 6089
      pos 7969
      pos 8039
      pos 8440
      pos 8959
    doc 3
      freq 25
      pos 102
      pos 142
      pos 345
      pos 388
      pos 412
      pos 420
      pos 444
      pos 491
      pos 590
      pos 733
      pos 839
      pos 2185
      pos 2218
      pos 2233
      pos 2258
      pos 2674
      pos 3028
      pos 3061
      pos 4070
      pos 4089
      pos 4101
      pos 4207
      pos 4318
      pos 4342
      pos 4370
    doc 8
      freq 17
      pos 23
      pos 72
      pos 127
      pos 155
      pos 482
      pos 492
      pos 582
      pos 619
      pos 819
      pos 997
      pos 1509
      pos 1519
      pos 1574
      pos 1586
      pos 1593
      pos 1798
      pos 2109
  term pseudowires
    doc 1
      freq 21
      pos 138
      pos 145
      pos 175
      pos 616
      pos 636
      pos 684
      pos 749
      pos 768
      pos 774
      pos 973
      pos 982
      pos 1292
      pos 1315
      pos 1330
      pos 1911
      pos 2153
      pos 2207
      pos 2258
      pos 7944
      pos 7950
      pos 8438
    doc 3
      freq 2
      pos 703
      pos 1217
  term psn
    doc 1
      freq 20
      pos 544
      pos 642
      pos 907
      pos 925
      pos 1017
      pos 1092
      pos 1094
      pos 1096
      pos 1098
      pos 1100
      pos 1104
      pos 1506
      pos 8017
      pos 8034
      pos 8118
      pos 8271
      pos 8319
      pos 8326
      pos 8363
      pos 8399
    doc 3
      freq 44
      pos 271
      pos 317
      pos 382
      pos 591
      pos 736
      pos 737
      pos 739
      pos 876
      pos 884
      pos 893
      pos 901
      pos 1289
      pos 1310
      pos 1607
      pos 1681
      pos 2242
      pos 2950
      pos 2991
      pos 3072
      pos 3333
      pos 3878
      pos 3894
      pos 3932
      pos 3973
      pos 3989
      pos 4001
      pos 4042
      pos 4095
      pos 4114
      pos 4117
      pos 4175
      pos 4180
      pos 4252
      pos 4277
      pos 4331
      pos 5401
      pos 5442
      pos 5537
      pos 5568
      pos 5603
      pos 5611
      pos 5631
      pos 5666
      pos 5852
    doc 8
      freq 3
      pos 1615
      pos 1624
      pos 2122
  term psnp
    doc 0
      freq 1
      pos 8719
  term psnps
    doc 0
      freq 1
      pos 8740
  term psns
    doc 1
      freq 1
      pos 667
  term pt
    doc 12
      freq 6
      pos 415
      pos 6520
      pos 6530
      pos 6562
      pos 7483
      pos 7668
  term pt8bsu3xinufn
    doc 10
      freq 1
      pos 12755
  term ptptcircuitid
    doc 0
      freq 1
      pos 6713
  term ptr
    doc 12
      freq 2
      pos 774
      pos 5352
  term pttopt
    doc 0
      freq 1
      pos 5724
  term pubkey
    doc 10
      freq 1
      pos 12330
  term public
    doc 5
      freq 2
      pos 778
      pos 3647
    doc 9
      freq 1
      pos 652
    doc 10
      freq 6
      pos 1670
      pos 2903
      pos 12301
      pos 12332
      pos 13239
      pos 13262
    doc 12
      freq 4
      pos 1409
      pos 5892
      pos 6915
      pos 8001
    doc 13
      freq 2
      pos 4213
      pos 6055
    doc 17
      freq 3
      pos 167
      pos 2059
      pos 2137
  term publication
    doc 2
      freq 11
      pos 1975
      pos 4096
      pos 4549
      pos 4580
      pos 4645
      pos 5105
      pos 5495
      pos 5507
      pos 5564
      pos 5590
      pos 6256
    doc 4
      freq 3
      pos 4817
      pos 4844
      pos 4979
  term publickeycert
    doc 17
      freq 1
      pos 1796
  term publish
    doc 2
      freq 1
      pos 4773
    doc 6
      freq 2
      pos 118
      pos 148
    doc 12
      freq 3
      pos 2074
      pos 7684
      pos 7688
  term published
    doc 0
      freq 1
      pos 1243
    doc 2
      freq 8
      pos 1356
      pos 3561
      pos 3994
      pos 4575
      pos 4627
      pos 4695
      pos 5099
      pos 5955
    doc 4
      freq 2
      pos 4905
      pos 4991
    doc 5
      freq 1
      pos 164
    doc 12
      freq 2
      pos 1301
      pos 7998
    doc 15
      freq 1
      pos 359
    doc 17
      freq 1
      pos 1024
    doc 18
      freq 1
      pos 514
    skipList 
      level 0
        skipDoc 18
        skipDocFP 1848226
        impacts 
          impact 
            freq 1
            norm 97
          impact 
            freq 8
            norm 108
        impactsEnd 
  term publishing
    doc 16
      freq 1
      pos 1646
  term purge
    doc 0
      freq 1
      pos 13024
  term purged
    doc 0
      freq 1
      pos 11889
  term purpos
    doc 0
      freq 1
      pos 17331
    doc 1
      freq 7
      pos 1114
      pos 2430
      pos 2848
      pos 5568
      pos 7251
      pos 7946
      pos 9712
    doc 2
      freq 3
      pos 1780
      pos 4072
      pos 6509
    doc 3
      freq 3
      pos 770
      pos 2666
      pos 6061
    doc 4
      freq 1
      pos 6216
    doc 5
      freq 2
      pos 3280
      pos 4546
    doc 6
      freq 3
      pos 520
      pos 844
      pos 3346
    doc 7
      freq 2
      pos 177
      pos 3051
    doc 8
      freq 1
      pos 2268
    doc 9
      freq 1
      pos 1913
    doc 10
      freq 2
      pos 9102
      pos 13574
    doc 11
      freq 1
      pos 10735
    doc 12
      freq 4
      pos 547
      pos 1365
      pos 5119
      pos 9585
    doc 13
      freq 3
      pos 3839
      pos 3865
      pos 7200
    doc 14
      freq 2
      pos 2393
      pos 5666
    doc 15
      freq 1
      pos 4185
    doc 16
      freq 1
      pos 2796
    doc 17
      freq 4
      pos 222
      pos 413
      pos 686
      pos 2520
    doc 18
      freq 1
      pos 2308
    skipList 
      level 0
        skipDoc 7
        skipDocFP 1849067
        impacts 
          impact 
            freq 2
            norm 100
          impact 
            freq 3
            norm 101
          impact 
            freq 7
            norm 113
        impactsEnd 
        skipDoc 15
        skipDocFP 1849578
        impacts 
          impact 
            freq 1
            norm 95
          impact 
            freq 2
            norm 107
          impact 
            freq 3
            norm 109
          impact 
            freq 4
            norm 113
        impactsEnd 
  term purposes
    doc 4
      freq 2
      pos 3698
      pos 3864
    doc 5
      freq 1
      pos 651
    doc 6
      freq 1
      pos 713
    doc 10
      freq 6
      pos 429
      pos 6097
      pos 7717
      pos 8131
      pos 8380
      pos 8410
    doc 12
      freq 1
      pos 1158
    doc 14
      freq 1
      pos 2596
    doc 16
      freq 1
      pos 436
  term push
    doc 0
      freq 1
      pos 16422
    doc 13
      freq 2
      pos 730
      pos 746
  term pushed
    doc 13
      freq 1
      pos 5685
  term pushes
    doc 1
      freq 1
      pos 1514
  term pushing
    doc 1
      freq 1
      pos 1280
    doc 12
      freq 1
      pos 9338
  term put
    doc 2
      freq 3
      pos 313
      pos 393
      pos 4443
    doc 4
      freq 1
      pos 4011
    doc 10
      freq 1
      pos 7635
    doc 13
      freq 1
      pos 466
    doc 16
      freq 1
      pos 791
  term putting
    doc 1
      freq 1
      pos 1270
    doc 15
      freq 1
      pos 2912
  term pw
    doc 1
      freq 177
      pos 279
      pos 302
      pos 322
      pos 333
      pos 1010
      pos 1088
      pos 1090
      pos 1471
      pos 1490
      pos 1532
      pos 1554
      pos 1571
      pos 1594
      pos 1626
      pos 1652
      pos 1682
      pos 1685
      pos 1745
      pos 1791
      pos 1815
      pos 1882
      pos 2002
      pos 2053
      pos 2295
      pos 2300
      pos 2306
      pos 2367
      pos 2380
      pos 2489
      pos 2491
      pos 2496
      pos 2502
      pos 2516
      pos 2558
      pos 2567
      pos 2579
      pos 2585
      pos 2615
      pos 2647
      pos 2671
      pos 2715
      pos 2728
      pos 2741
      pos 2746
      pos 2750
      pos 2754
      pos 2886
      pos 2889
      pos 2915
      pos 2934
      pos 2940
      pos 3018
      pos 3384
      pos 3401
      pos 3676
      pos 3678
      pos 3814
      pos 3958
      pos 4036
      pos 4071
      pos 4112
      pos 4120
      pos 4146
      pos 4169
      pos 4196
      pos 4212
      pos 4230
      pos 4278
      pos 4291
      pos 4305
      pos 4433
      pos 4607
      pos 4713
      pos 4732
      pos 4778
      pos 4827
      pos 4840
      pos 4856
      pos 4883
      pos 4895
      pos 4901
      pos 4911
      pos 4929
      pos 4961
      pos 4972
      pos 4979
      pos 4998
      pos 5026
      pos 5043
      pos 5060
      pos 5102
      pos 5121
      pos 5185
      pos 5218
      pos 5278
      pos 5312
      pos 5317
      pos 5342
      pos 5374
      pos 5390
      pos 5408
      pos 5416
      pos 5436
      pos 5454
      pos 5504
      pos 5513
      pos 5544
      pos 5553
      pos 5578
      pos 5610
      pos 5625
      pos 5638
      pos 5652
      pos 5661
      pos 5748
      pos 5756
      pos 5769
      pos 5782
      pos 5787
      pos 5799
      pos 5803
      pos 5813
      pos 5819
      pos 5846
      pos 5873
      pos 5886
      pos 5896
      pos 5930
      pos 5936
      pos 5942
      pos 5951
      pos 5958
      pos 6192
      pos 6206
      pos 6208
      pos 6251
      pos 6289
      pos 6323
      pos 6352
      pos 6372
      pos 6395
      pos 6408
      pos 6432
      pos 6467
      pos 6504
      pos 6516
      pos 6563
      pos 6603
      pos 6635
      pos 6652
      pos 6779
      pos 6806
      pos 6866
      pos 6911
      pos 6955
      pos 7109
      pos 7126
      pos 7132
      pos 7160
      pos 7169
      pos 7220
      pos 7229
      pos 7286
      pos 7324
      pos 7360
      pos 7618
      pos 7719
      pos 7781
      pos 7785
      pos 7859
      pos 7878
      pos 8064
      pos 8253
      pos 8268
      pos 8283
      pos 8308
      pos 9464
    doc 3
      freq 110
      pos 103
      pos 151
      pos 346
      pos 389
      pos 499
      pos 551
      pos 569
      pos 593
      pos 599
      pos 815
      pos 868
      pos 874
      pos 891
      pos 910
      pos 914
      pos 965
      pos 987
      pos 1005
      pos 1006
      pos 1028
      pos 1072
      pos 1086
      pos 1101
      pos 1121
      pos 1159
      pos 1166
      pos 1187
      pos 1268
      pos 1294
      pos 1316
      pos 1330
      pos 1339
      pos 1381
      pos 1406
      pos 1480
      pos 1506
      pos 1515
      pos 1520
      pos 1553
      pos 1642
      pos 1655
      pos 1665
      pos 1769
      pos 1807
      pos 1835
      pos 1887
      pos 1917
      pos 1922
      pos 2095
      pos 2106
      pos 2137
      pos 2187
      pos 2270
      pos 2281
      pos 2286
      pos 2485
      pos 2499
      pos 2536
      pos 2540
      pos 2551
      pos 2596
      pos 2621
      pos 2710
      pos 2841
      pos 2866
      pos 2967
      pos 3000
      pos 3012
      pos 3062
      pos 3081
      pos 3188
      pos 3219
      pos 3225
      pos 3236
      pos 3258
      pos 3276
      pos 3295
      pos 3320
      pos 3395
      pos 3438
      pos 3455
      pos 3488
      pos 3528
      pos 3590
      pos 3689
      pos 3869
      pos 3961
      pos 3970
      pos 3983
      pos 4036
      pos 4045
      pos 4153
      pos 4532
      pos 4542
      pos 4600
      pos 5033
      pos 5146
      pos 5186
      pos 5221
      pos 5249
      pos 5264
      pos 5275
      pos 5438
      pos 5459
      pos 5481
      pos 5489
      pos 5503
      pos 5646
      pos 5812
      pos 5834
    doc 8
      freq 11
      pos 159
      pos 500
      pos 512
      pos 532
      pos 552
      pos 626
      pos 1617
      pos 1626
      pos 1636
      pos 1645
      pos 1654
  term pw1
    doc 1
      freq 1
      pos 1032
    doc 3
      freq 1
      pos 607
  term pw2
    doc 1
      freq 1
      pos 1035
    doc 3
      freq 1
      pos 610
  term pwe3
    doc 1
      freq 38
      pos 206
      pos 429
      pos 837
      pos 1054
      pos 1066
      pos 1107
      pos 1374
      pos 1867
      pos 2227
      pos 2423
      pos 2530
      pos 2697
      pos 3056
      pos 3426
      pos 3611
      pos 3908
      pos 4245
      pos 4639
      pos 5019
      pos 5298
      pos 5690
      pos 6025
      pos 6094
      pos 6366
      pos 6761
      pos 7199
      pos 7641
      pos 7891
      pos 8239
      pos 8707
      pos 8964
      pos 9022
      pos 9159
      pos 9226
      pos 9333
      pos 9403
      pos 9498
      pos 9599
    doc 3
      freq 23
      pos 406
      pos 449
      pos 637
      pos 747
      pos 1080
      pos 1985
      pos 3041
      pos 3232
      pos 3283
      pos 3315
      pos 3606
      pos 3780
      pos 4085
      pos 4309
      pos 4323
      pos 4347
      pos 4354
      pos 4526
      pos 4567
      pos 4584
      pos 4589
      pos 4633
      pos 4651
    doc 8
      freq 14
      pos 28
      pos 92
      pos 190
      pos 211
      pos 477
      pos 802
      pos 1129
      pos 1443
      pos 1673
      pos 1836
      pos 1854
      pos 1934
      pos 2114
      pos 2157
  term pwes
    doc 3
      freq 5
      pos 3964
      pos 3978
      pos 3994
      pos 5530
      pos 5554
  term pwid
    doc 1
      freq 25
      pos 250
      pos 257
      pos 2388
      pos 2392
      pos 2486
      pos 2851
      pos 2894
      pos 2898
      pos 2928
      pos 2977
      pos 2986
      pos 3000
      pos 3029
      pos 3127
      pos 3130
      pos 3673
      pos 4396
      pos 4403
      pos 5281
      pos 5449
      pos 5498
      pos 5731
      pos 7104
      pos 7154
      pos 7307
  term pws
    doc 1
      freq 13
      pos 2605
      pos 2638
      pos 3221
      pos 3290
      pos 3839
      pos 4135
      pos 4142
      pos 4160
      pos 5478
      pos 6184
      pos 6311
      pos 7293
      pos 8224
    doc 3
      freq 6
      pos 1449
      pos 1475
      pos 1813
      pos 1831
      pos 3998
      pos 5523
  term pwv
    doc 11
      freq 1
      pos 10245
  term pxb6uaour
    doc 10
      freq 1
      pos 12610
  term pxou8t2mzpi0wk4hx4tzhntiwgkkupc3h9bjp
    doc 10
      freq 1
      pos 6217
  term pzu8
    doc 11
      freq 1
      pos 10249
  term q
    doc 2
      freq 1
      pos 4107
    doc 11
      freq 3
      pos 1530
      pos 4874
      pos 9941
  term q4jurdpahrl8jsxz
    doc 11
      freq 1
      pos 9972
  term q7n6su3
    doc 10
      freq 1
      pos 12719
  term q7ni3ex2
    doc 11
      freq 1
      pos 10225
  term qaqhmuezvuf2vhlrbuklloghurhna24cilv4d3yacvuetymncuytwhkj24wfaka
    doc 10
      freq 1
      pos 6862
  term qbbr
    doc 10
      freq 1
      pos 12557
  term qbgsh0mskj646rexi3k8nkslahl9nlrrqdvtsbwrvidvdwyrtzd
    doc 10
      freq 1
      pos 12546
  term qcheofuleg
    doc 10
      freq 1
      pos 12579
  term qcz
    doc 11
      freq 1
      pos 10279
  term qf1h2oz9tiepwfabah0chpwewo4kujf9fxqhadiqyoqcjxgobitabz
    doc 11
      freq 1
      pos 10491
  term qh4kwqbemetdqpbwyjyofrkol9e69mqk
    doc 11
      freq 1
      pos 10308
  term qie6pd50k
    doc 11
      freq 1
      pos 10323
  term qix9vb70tcnhgdoqg4apb
    doc 11
      freq 1
      pos 10502
  term qm
    doc 11
      freq 1
      pos 10381
  term qname
    doc 14
      freq 4
      pos 2629
      pos 2722
      pos 2780
      pos 2798
    doc 18
      freq 3
      pos 774
      pos 788
      pos 1081
  term qncsaaf3xkugffklx5okcrakea7uxnse8xat30
    doc 10
      freq 1
      pos 6221
  term qos
    doc 1
      freq 1
      pos 985
    doc 3
      freq 15
      pos 263
      pos 307
      pos 541
      pos 1685
      pos 3783
      pos 3810
      pos 3835
      pos 3890
      pos 3928
      pos 3942
      pos 5427
      pos 5431
      pos 5439
      pos 5853
      pos 5858
    doc 6
      freq 5
      pos 320
      pos 347
      pos 469
      pos 489
      pos 2313
  term qqn24c5szjnklejj01kwloqwhtixnybywk
    doc 11
      freq 1
      pos 10004
  term qqty8jjabmggiytv7b7t09pt0xnl
    doc 10
      freq 1
      pos 12457
  term qt
    doc 10
      freq 1
      pos 12506
    doc 17
      freq 18
      pos 836
      pos 843
      pos 848
      pos 851
      pos 856
      pos 859
      pos 880
      pos 884
      pos 905
      pos 912
      pos 915
      pos 2263
      pos 2270
      pos 2275
      pos 2278
      pos 2283
      pos 2342
      pos 2345
  term qtype
    doc 12
      freq 2
      pos 1149
      pos 1166
  term qualcomm
    doc 16
      freq 2
      pos 9
      pos 2653
  term qualcomm.com
    doc 16
      freq 1
      pos 2671
  term qualifier
    doc 17
      freq 11
      pos 825
      pos 919
      pos 926
      pos 987
      pos 997
      pos 1013
      pos 1041
      pos 1228
      pos 2333
      pos 2349
      pos 2356
  term qualifiers
    doc 17
      freq 3
      pos 834
      pos 1009
      pos 2261
  term quality
    doc 2
      freq 3
      pos 1257
      pos 1301
      pos 1312
    doc 3
      freq 2
      pos 538
      pos 1671
    doc 6
      freq 8
      pos 195
      pos 317
      pos 849
      pos 2682
      pos 2912
      pos 2923
      pos 2944
      pos 2999
    doc 12
      freq 2
      pos 2732
      pos 2765
    doc 18
      freq 1
      pos 1800
  term quantities
    doc 1
      freq 1
      pos 3485
    doc 6
      freq 1
      pos 2164
    doc 13
      freq 1
      pos 4015
  term quantity
    doc 1
      freq 1
      pos 2507
    doc 13
      freq 1
      pos 5439
  term qucnh4bdc9hzv8ikcksn5wm83neionkavbqls4mlanoplaqn67jbmlq2xspumqa1
    doc 10
      freq 1
      pos 12525
  term queried
    doc 12
      freq 5
      pos 921
      pos 926
      pos 1738
      pos 3091
      pos 4107
  term queries
    doc 12
      freq 17
      pos 912
      pos 1168
      pos 1211
      pos 1697
      pos 1709
      pos 3048
      pos 3111
      pos 3123
      pos 3338
      pos 3416
      pos 3447
      pos 3529
      pos 3717
      pos 7378
      pos 8174
      pos 8845
      pos 9100
    doc 14
      freq 6
      pos 2626
      pos 2719
      pos 2747
      pos 2777
      pos 2795
      pos 5305
    doc 18
      freq 3
      pos 253
      pos 325
      pos 948
  term query
    doc 10
      freq 1
      pos 11269
    doc 12
      freq 21
      pos 177
      pos 330
      pos 960
      pos 1075
      pos 1143
      pos 1765
      pos 1777
      pos 1791
      pos 2938
      pos 3251
      pos 3478
      pos 3490
      pos 3542
      pos 3553
      pos 8723
      pos 8738
      pos 8750
      pos 8932
      pos 9124
      pos 9152
      pos 9279
    doc 13
      freq 1
      pos 2596
    doc 14
      freq 2
      pos 326
      pos 352
    doc 15
      freq 2
      pos 1800
      pos 1964
    doc 18
      freq 3
      pos 972
      pos 1038
      pos 1363
  term querying
    doc 12
      freq 1
      pos 1055
  term question
    doc 7
      freq 1
      pos 564
    doc 10
      freq 3
      pos 2477
      pos 6018
      pos 7680
    doc 12
      freq 1
      pos 7692
    doc 13
      freq 1
      pos 5508
    doc 15
      freq 4
      pos 863
      pos 1192
      pos 1220
      pos 3496
  term questionabl
    doc 10
      freq 1
      pos 11090
    doc 12
      freq 1
      pos 6961
  term queue
    doc 7
      freq 1
      pos 2859
  term queued
    doc 0
      freq 11
      pos 12909
      pos 13163
      pos 13265
      pos 13482
      pos 13580
      pos 13672
      pos 13774
      pos 13847
      pos 13931
      pos 14059
      pos 14188
  term queuing
    doc 3
      freq 1
      pos 3851
  term quickly
    doc 6
      freq 2
      pos 959
      pos 2576
    doc 12
      freq 1
      pos 3643
  term quinn
    doc 13
      freq 1
      pos 6921
  term quite
    doc 9
      freq 1
      pos 1592
    doc 10
      freq 2
      pos 1731
      pos 1748
    doc 12
      freq 1
      pos 6933
  term quotbal
    doc 11
      freq 1
      pos 5150
  term quotbal.aksdj
    doc 11
      freq 1
      pos 5172
  term quote
    doc 11
      freq 2
      pos 5090
      pos 5119
  term quoted
    doc 11
      freq 10
      pos 284
      pos 1037
      pos 1123
      pos 1523
      pos 1672
      pos 1675
      pos 1680
      pos 1702
      pos 1794
      pos 5078
  term quotes
    doc 11
      freq 2
      pos 1220
      pos 6549
  term qviwjti2
    doc 10
      freq 1
      pos 12654
  term qvzkoou
    doc 11
      freq 1
      pos 10106
  term qwbv8u6d8fqocievaeak
    doc 11
      freq 1
      pos 10341
  term qweoiqp
    doc 11
      freq 1
      pos 6694
  term qx2bhld1u2cccu4arbiemqiqhigbkaaq2b6q
    doc 11
      freq 1
      pos 10469
  term qzbsuzmxq0auktszle6whdm3fbku5xzlcpt2l
    doc 10
      freq 1
      pos 12780
  term qzkl
    doc 11
      freq 1
      pos 10157
  term qzt
    doc 11
      freq 1
      pos 10175
  term r
    doc 0
      freq 5
      pos 16962
      pos 17018
      pos 17133
      pos 17151
      pos 17176
    doc 1
      freq 1
      pos 8980
    doc 2
      freq 2
      pos 2294
      pos 2325
    doc 3
      freq 2
      pos 4391
      pos 4666
    doc 4
      freq 4
      pos 5180
      pos 5253
      pos 5331
      pos 5370
    doc 5
      freq 6
      pos 833
      pos 4188
      pos 4259
      pos 4327
      pos 4377
      pos 4390
    doc 6
      freq 7
      pos 2236
      pos 2871
      pos 2905
      pos 2939
      pos 2968
      pos 3047
      pos 3068
    doc 8
      freq 4
      pos 1816
      pos 1870
      pos 2040
      pos 2042
    doc 9
      freq 1
      pos 1707
    doc 10
      freq 9
      pos 5794
      pos 5825
      pos 6236
      pos 12724
      pos 13102
      pos 13202
      pos 13228
      pos 13255
      pos 13381
    doc 11
      freq 3
      pos 3
      pos 9641
      pos 9679
    doc 12
      freq 15
      pos 7036
      pos 7038
      pos 7051
      pos 7053
      pos 7127
      pos 7160
      pos 7173
      pos 7198
      pos 7241
      pos 7282
      pos 7300
      pos 7392
      pos 7410
      pos 7425
      pos 7575
    doc 13
      freq 4
      pos 13
      pos 6840
      pos 6858
      pos 6882
    doc 14
      freq 5
      pos 5392
      pos 5394
      pos 5430
      pos 5432
      pos 5490
    doc 15
      freq 4
      pos 3900
      pos 3925
      pos 3939
      pos 3964
    doc 17
      freq 2
      pos 2048
      pos 2077
    doc 18
      freq 6
      pos 2061
      pos 2063
      pos 2082
      pos 2084
      pos 2105
      pos 2107
    skipList 
      level 0
        skipDoc 8
        skipDocFP 1865272
        impacts 
          impact 
            freq 4
            norm 97
          impact 
            freq 7
            norm 101
        impactsEnd 
        skipDoc 17
        skipDocFP 1865925
        impacts 
          impact 
            freq 1
            norm 95
          impact 
            freq 2
            norm 98
          impact 
            freq 4
            norm 104
          impact 
            freq 5
            norm 107
          impact 
            freq 15
            norm 113
        impactsEnd 
  term r0sbivccdq1jrk5moyzv1s44tjjo3o5azalzcbtr
    doc 11
      freq 1
      pos 10104
  term r0y9yshxurrhlxrf
    doc 10
      freq 1
      pos 12782
  term r2006
    doc 12
      freq 2
      pos 3634
      pos 7772
  term r2bva
    doc 10
      freq 1
      pos 6225
  term r3h
    doc 11
      freq 1
      pos 9957
  term r3iqcehiq
    doc 10
      freq 1
      pos 12611
  term r5haqafvm1q6zwj0zk
    doc 11
      freq 1
      pos 9973
  term r5mwreluydryb
    doc 11
      freq 1
      pos 3800
  term r9
    doc 11
      freq 1
      pos 10166
  term r9kgvp5vtkzqkfcgemduojvt
    doc 11
      freq 1
      pos 10338
  term ra
    doc 0
      freq 1
      pos 14711
    doc 11
      freq 1
      pos 9931
  term radext
    doc 2
      freq 2
      pos 1524
      pos 5270
  term radio
    doc 13
      freq 10
      pos 205
      pos 548
      pos 2029
      pos 2083
      pos 2871
      pos 2907
      pos 2964
      pos 2994
      pos 3020
      pos 3082
  term radius
    doc 2
      freq 28
      pos 281
      pos 293
      pos 1561
      pos 1595
      pos 2166
      pos 2189
      pos 2195
      pos 3032
      pos 3040
      pos 3054
      pos 3079
      pos 3097
      pos 3111
      pos 3124
      pos 3141
      pos 3178
      pos 4881
      pos 5045
      pos 5066
      pos 5090
      pos 5254
      pos 5290
      pos 6138
      pos 6166
      pos 6176
      pos 6197
      pos 6285
      pos 6313
  term radoac
    doc 1
      freq 1
      pos 9312
    doc 3
      freq 1
      pos 4813
    doc 8
      freq 1
      pos 2087
  term rafi
    doc 11
      freq 1
      pos 9467
  term raisanen
    doc 6
      freq 1
      pos 2996
  term raise
    doc 16
      freq 1
      pos 1605
  term raised
    doc 2
      freq 2
      pos 4749
      pos 6279
    doc 15
      freq 1
      pos 826
  term raising
    doc 0
      freq 1
      pos 16036
  term raj
    doc 3
      freq 2
      pos 4945
      pos 4957
  term ralph
    doc 12
      freq 1
      pos 6802
    doc 15
      freq 1
      pos 3849
  term ramachandran
    doc 0
      freq 1
      pos 15959
  term ramalingam
    doc 0
      freq 1
      pos 15961
  term ran
    doc 0
      freq 1
      pos 7695
    doc 5
      freq 1
      pos 4074
  term random
    doc 5
      freq 3
      pos 3928
      pos 3942
      pos 3965
    doc 12
      freq 2
      pos 1338
      pos 8967
  term randomness
    doc 9
      freq 3
      pos 811
      pos 1076
      pos 1693
  term range
    doc 0
      freq 3
      pos 1624
      pos 1711
      pos 2004
    doc 1
      freq 1
      pos 7827
    doc 4
      freq 1
      pos 895
    doc 5
      freq 4
      pos 3778
      pos 3806
      pos 3994
      pos 4022
    doc 6
      freq 2
      pos 730
      pos 1085
    doc 8
      freq 8
      pos 235
      pos 246
      pos 260
      pos 437
      pos 599
      pos 977
      pos 1271
      pos 1466
    doc 10
      freq 1
      pos 1006
    doc 11
      freq 8
      pos 144
      pos 1012
      pos 1582
      pos 1591
      pos 1737
      pos 4756
      pos 4964
      pos 4991
    doc 13
      freq 2
      pos 2742
      pos 3881
    doc 14
      freq 6
      pos 182
      pos 2007
      pos 2046
      pos 2097
      pos 2270
      pos 2914
    doc 18
      freq 1
      pos 107
    skipList 
      level 0
        skipDoc 11
        skipDocFP 1869930
        impacts 
          impact 
            freq 8
            norm 97
        impactsEnd 
  term ranges
    doc 0
      freq 1
      pos 4073
    doc 8
      freq 1
      pos 233
  term ranging
    doc 6
      freq 1
      pos 766
  term raoeyfs13wpfxy5w3ufn0xlthybvr6ogghfvzpbgesk5zv0d4pgpsvsfcnw6
    doc 11
      freq 1
      pos 10048
  term rapidly
    doc 0
      freq 1
      pos 13043
  term raquot
    doc 10
      freq 1
      pos 4830
  term rastog
    doc 11
      freq 1
      pos 9487
  term rate
    doc 1
      freq 5
      pos 149
      pos 656
      pos 675
      pos 2360
      pos 7848
    doc 3
      freq 2
      pos 4038
      pos 4064
    doc 4
      freq 8
      pos 1843
      pos 1871
      pos 1890
      pos 1900
      pos 1943
      pos 1981
      pos 4390
      pos 5594
    doc 6
      freq 34
      pos 596
      pos 602
      pos 618
      pos 634
      pos 644
      pos 673
      pos 1159
      pos 1196
      pos 1202
      pos 1206
      pos 1214
      pos 1217
      pos 1224
      pos 1231
      pos 1246
      pos 1252
      pos 1281
      pos 1321
      pos 1355
      pos 1436
      pos 1483
      pos 1548
      pos 1558
      pos 1781
      pos 2039
      pos 2043
      pos 2163
      pos 2184
      pos 2194
      pos 2235
      pos 2329
      pos 2385
      pos 2703
      pos 2843
    doc 8
      freq 1
      pos 1062
  term rates
    doc 6
      freq 3
      pos 238
      pos 1387
      pos 1440
  term rather
    doc 1
      freq 4
      pos 2971
      pos 8185
      pos 8826
      pos 8853
    doc 2
      freq 6
      pos 1394
      pos 1499
      pos 1623
      pos 1888
      pos 3660
      pos 4399
    doc 10
      freq 2
      pos 5006
      pos 6069
    doc 12
      freq 6
      pos 1638
      pos 2266
      pos 4529
      pos 6276
      pos 6461
      pos 9353
    doc 13
      freq 3
      pos 3814
      pos 4925
      pos 6534
    doc 14
      freq 1
      pos 2808
    doc 15
      freq 1
      pos 3617
    doc 17
      freq 1
      pos 481
    doc 18
      freq 1
      pos 637
    skipList 
      level 0
        skipDoc 17
        skipDocFP 1872271
        impacts 
          impact 
            freq 1
            norm 98
          impact 
            freq 6
            norm 108
        impactsEnd 
  term rational
    doc 4
      freq 1
      pos 1327
    doc 15
      freq 1
      pos 3416
  term ravikumar
    doc 0
      freq 1
      pos 15963
  term raw
    doc 3
      freq 13
      pos 206
      pos 223
      pos 1128
      pos 1185
      pos 1844
      pos 1862
      pos 2325
      pos 2489
      pos 2733
      pos 2797
      pos 5057
      pos 5058
      pos 5111
  term raytheon
    doc 17
      freq 2
      pos 9
      pos 2370
  term raytheon.com
    doc 17
      freq 1
      pos 2383
  term rb
    doc 10
      freq 1
      pos 12737
  term rbegngxdvtpe3dnh8ai1799bvxwdiiqugqvnakcrmmogf5ty
    doc 11
      freq 1
      pos 10476
  term rcafi
    doc 11
      freq 1
      pos 9903
  term rd
    doc 11
      freq 1
      pos 10241
  term rd3dkx7zp
    doc 11
      freq 1
      pos 10266
  term rdata
    doc 14
      freq 1
      pos 2327
  term rdbms
    doc 7
      freq 1
      pos 2597
  term rdp2004
    doc 12
      freq 2
      pos 3615
      pos 7789
  term rdquot
    doc 10
      freq 1
      pos 4814
  term rdx5nqoru
    doc 10
      freq 1
      pos 6254
  term re
    doc 0
      freq 5
      pos 6157
      pos 7035
      pos 7067
      pos 9347
      pos 13028
    doc 1
      freq 3
      pos 7418
      pos 7535
      pos 7648
    doc 10
      freq 1
      pos 11593
    doc 11
      freq 2
      pos 2553
      pos 2585
    doc 12
      freq 3
      pos 6941
      pos 9099
      pos 9126
    doc 13
      freq 1
      pos 795
    doc 14
      freq 1
      pos 2729
    doc 16
      freq 1
      pos 351
    skipList 
      level 0
        skipDoc 16
        skipDocFP 1874182
        impacts 
          impact 
            freq 1
            norm 99
          impact 
            freq 3
            norm 113
          impact 
            freq 5
            norm 120
        impactsEnd 
  term reach
    doc 0
      freq 3
      pos 3567
      pos 10561
      pos 11617
    doc 10
      freq 2
      pos 448
      pos 3515
    doc 12
      freq 2
      pos 2257
      pos 4162
  term reachability
    doc 0
      freq 2
      pos 3560
      pos 11165
  term reachabl
    doc 0
      freq 33
      pos 834
      pos 858
      pos 868
      pos 3393
      pos 9939
      pos 9943
      pos 9952
      pos 9985
      pos 10011
      pos 10094
      pos 10120
      pos 10181
      pos 10209
      pos 10271
      pos 10364
      pos 10571
      pos 10603
      pos 10760
      pos 10825
      pos 10860
      pos 10870
      pos 10900
      pos 10934
      pos 10944
      pos 10961
      pos 11085
      pos 11118
      pos 11365
      pos 11417
      pos 11469
      pos 11624
      pos 15729
      pos 16341
    doc 4
      freq 1
      pos 1244
    doc 12
      freq 1
      pos 9135
  term reached
    doc 10
      freq 1
      pos 1134
    doc 12
      freq 1
      pos 4040
    doc 15
      freq 2
      pos 3602
      pos 3683
  term reaches
    doc 1
      freq 2
      pos 1542
      pos 1718
  term reaching
    doc 0
      freq 3
      pos 10481
      pos 11511
      pos 11575
  term reaction
    doc 4
      freq 1
      pos 4688
  term read
    doc 0
      freq 185
      pos 2257
      pos 2275
      pos 2293
      pos 2336
      pos 2389
      pos 2471
      pos 2548
      pos 2617
      pos 2669
      pos 2727
      pos 2774
      pos 2812
      pos 2860
      pos 2953
      pos 2979
      pos 3236
      pos 3471
      pos 3885
      pos 3928
      pos 3958
      pos 4385
      pos 4588
      pos 4615
      pos 4759
      pos 4828
      pos 4868
      pos 4967
      pos 5032
      pos 5144
      pos 5173
      pos 5203
      pos 5244
      pos 5313
      pos 5595
      pos 5628
      pos 5650
      pos 5734
      pos 5793
      pos 5830
      pos 5907
      pos 5958
      pos 6023
      pos 6083
      pos 6110
      pos 6137
      pos 6193
      pos 6217
      pos 6405
      pos 6446
      pos 6472
      pos 6506
      pos 6614
      pos 6724
      pos 6785
      pos 6844
      pos 6938
      pos 6985
      pos 7025
      pos 7103
      pos 7160
      pos 7317
      pos 7390
      pos 7423
      pos 7448
      pos 7475
      pos 7505
      pos 7548
      pos 7575
      pos 7619
      pos 7658
      pos 7686
      pos 7719
      pos 7902
      pos 7933
      pos 7970
      pos 8011
      pos 8050
      pos 8091
      pos 8145
      pos 8182
      pos 8216
      pos 8444
      pos 8512
      pos 8570
      pos 8628
      pos 8685
      pos 8730
      pos 8772
      pos 8979
      pos 9010
      pos 9055
      pos 9100
      pos 9124
      pos 9150
      pos 9180
      pos 9254
      pos 9294
      pos 9324
      pos 9534
      pos 9716
      pos 9757
      pos 9919
      pos 10110
      pos 10159
      pos 10200
      pos 10245
      pos 10472
      pos 10509
      pos 10543
      pos 10619
      pos 10717
      pos 10817
      pos 11282
      pos 11316
      pos 11355
      pos 11407
      pos 11458
      pos 11502
      pos 11535
      pos 11565
      pos 11599
      pos 11675
      pos 11848
      pos 11868
      pos 11902
      pos 11926
      pos 11948
      pos 11967
      pos 12167
      pos 12199
      pos 12221
      pos 12240
      pos 12263
      pos 14774
      pos 14778
      pos 14785
      pos 14826
      pos 14838
      pos 14850
      pos 14862
      pos 14874
      pos 14886
      pos 14898
      pos 14910
      pos 14934
      pos 14946
      pos 14958
      pos 14970
      pos 14982
      pos 14994
      pos 15006
      pos 15018
      pos 15030
      pos 15042
      pos 15066
      pos 15078
      pos 15090
      pos 15102
      pos 15114
      pos 15126
      pos 15138
      pos 15150
      pos 15162
      pos 15186
      pos 15198
      pos 15210
      pos 15222
      pos 15234
      pos 15246
      pos 15258
      pos 15270
      pos 15282
      pos 15294
      pos 15318
      pos 15330
      pos 15342
      pos 15354
      pos 15366
      pos 15378
      pos 15390
      pos 16109
      pos 16113
      pos 16671
      pos 16697
      pos 16789
  term readabl
    doc 1
      freq 2
      pos 6233
      pos 6270
    doc 11
      freq 1
      pos 1208
  term reader
    doc 3
      freq 1
      pos 437
  term readers
    doc 6
      freq 1
      pos 154
  term readily
    doc 0
      freq 1
      pos 16675
    doc 6
      freq 1
      pos 895
  term readiness
    doc 12
      freq 1
      pos 3408
  term reads
    doc 0
      freq 1
      pos 5302
  term ready
    doc 2
      freq 1
      pos 4269
    doc 12
      freq 1
      pos 2086
    doc 16
      freq 11
      pos 1791
      pos 1819
      pos 1836
      pos 1944
      pos 2080
      pos 2172
      pos 2200
      pos 2312
      pos 2408
      pos 2427
      pos 2444
  term real
    doc 4
      freq 1
      pos 874
    doc 5
      freq 4
      pos 157
      pos 611
      pos 4229
      pos 4367
    doc 6
      freq 4
      pos 408
      pos 462
      pos 2471
      pos 3077
    doc 12
      freq 2
      pos 2758
      pos 8212
    doc 13
      freq 2
      pos 3001
      pos 3243
    doc 14
      freq 1
      pos 358
    doc 18
      freq 1
      pos 1108
  term realising
    doc 5
      freq 1
      pos 1912
  term realistically
    doc 7
      freq 1
      pos 1365
  term realities
    doc 10
      freq 1
      pos 10430
  term realized
    doc 5
      freq 1
      pos 140
  term realizing
    doc 5
      freq 1
      pos 2078
  term reallocated
    doc 9
      freq 1
      pos 1493
  term really
    doc 10
      freq 1
      pos 11404
    doc 11
      freq 1
      pos 2881
    doc 12
      freq 1
      pos 5382
    doc 15
      freq 1
      pos 2885
  term reallylong
    doc 11
      freq 1
      pos 971
  term reallylongsecondvalu
    doc 11
      freq 2
      pos 954
      pos 962
  term realm
    doc 10
      freq 1
      pos 2803
  term reason
    doc 0
      freq 2
      pos 6746
      pos 13813
    doc 4
      freq 6
      pos 2281
      pos 2341
      pos 2363
      pos 2444
      pos 2599
      pos 2632
    doc 7
      freq 3
      pos 385
      pos 390
      pos 1268
    doc 9
      freq 3
      pos 414
      pos 889
      pos 1217
    doc 10
      freq 8
      pos 3097
      pos 7828
      pos 9083
      pos 9225
      pos 11631
      pos 11726
      pos 11827
      pos 11921
    doc 11
      freq 10
      pos 236
      pos 241
      pos 2189
      pos 3917
      pos 3924
      pos 3930
      pos 3944
      pos 4080
      pos 4088
      pos 4101
    doc 12
      freq 1
      pos 6557
    doc 16
      freq 1
      pos 1243
    skipList 
      level 0
        skipDoc 16
        skipDocFP 1880852
        impacts 
          impact 
            freq 3
            norm 95
          impact 
            freq 6
            norm 108
          impact 
            freq 10
            norm 114
        impactsEnd 
  term reasonabl
    doc 4
      freq 1
      pos 1979
    doc 10
      freq 1
      pos 631
    doc 11
      freq 6
      pos 4440
      pos 5135
      pos 5263
      pos 6298
      pos 6411
      pos 6520
    doc 12
      freq 1
      pos 6694
    doc 15
      freq 1
      pos 3510
  term reasonably
    doc 1
      freq 1
      pos 7430
    doc 12
      freq 2
      pos 4478
      pos 5936
    doc 13
      freq 1
      pos 2440
    doc 18
      freq 1
      pos 1254
  term reasons
    doc 4
      freq 2
      pos 2260
      pos 2687
    doc 10
      freq 4
      pos 5927
      pos 9541
      pos 10044
      pos 12862
    doc 12
      freq 4
      pos 2021
      pos 3723
      pos 5923
      pos 7664
    doc 13
      freq 1
      pos 6516
    doc 15
      freq 1
      pos 1349
    doc 16
      freq 1
      pos 1268
  term reassembly
    doc 3
      freq 2
      pos 1617
      pos 4636
    doc 4
      freq 3
      pos 3087
      pos 3185
      pos 5688
    doc 8
      freq 1
      pos 1839
  term reassigned
    doc 4
      freq 2
      pos 4961
      pos 5070
    doc 12
      freq 1
      pos 6096
  term reassignment
    doc 7
      freq 2
      pos 696
      pos 1992
  term reassigns
    doc 12
      freq 1
      pos 6034
  term reboot
    doc 0
      freq 27
      pos 2373
      pos 2455
      pos 2516
      pos 2597
      pos 2649
      pos 2699
      pos 2762
      pos 2796
      pos 2844
      pos 2935
      pos 3019
      pos 3162
      pos 3443
      pos 3613
      pos 4129
      pos 4506
      pos 4695
      pos 5462
      pos 6330
      pos 8878
      pos 9480
      pos 9663
      pos 9889
      pos 10026
      pos 10970
      pos 11760
      pos 12099
  term rebooting
    doc 13
      freq 1
      pos 781
  term reboots
    doc 9
      freq 1
      pos 1321
  term rebuilding
    doc 17
      freq 1
      pos 1455
  term receipt
    doc 0
      freq 1
      pos 9280
    doc 1
      freq 1
      pos 7566
    doc 3
      freq 1
      pos 3716
    doc 5
      freq 1
      pos 2321
    doc 10
      freq 1
      pos 8523
  term receiv
    doc 0
      freq 11
      pos 5886
      pos 13086
      pos 13200
      pos 13289
      pos 13350
      pos 13420
      pos 13506
      pos 13605
      pos 13695
      pos 13798
      pos 14265
    doc 1
      freq 4
      pos 7530
      pos 9459
      pos 9470
      pos 9471
    doc 2
      freq 1
      pos 1029
    doc 3
      freq 2
      pos 3561
      pos 5422
    doc 6
      freq 2
      pos 1646
      pos 2246
    doc 8
      freq 2
      pos 1602
      pos 1619
    doc 10
      freq 6
      pos 615
      pos 1095
      pos 1143
      pos 8776
      pos 10054
      pos 12898
    doc 13
      freq 4
      pos 3607
      pos 4084
      pos 4547
      pos 6280
    doc 15
      freq 1
      pos 2690
    skipList 
      level 0
        skipDoc 13
        skipDocFP 1883909
        impacts 
          impact 
            freq 2
            norm 97
          impact 
            freq 4
            norm 109
          impact 
            freq 6
            norm 116
          impact 
            freq 11
            norm 120
        impactsEnd 
  term received
    doc 0
      freq 35
      pos 794
      pos 813
      pos 3343
      pos 3386
      pos 3430
      pos 4578
      pos 7330
      pos 7358
      pos 7593
      pos 7630
      pos 7716
      pos 7731
      pos 8077
      pos 8119
      pos 8172
      pos 8262
      pos 9272
      pos 9423
      pos 9547
      pos 9578
      pos 9622
      pos 9744
      pos 9770
      pos 9815
      pos 9847
      pos 9932
      pos 12431
      pos 12457
      pos 12493
      pos 12517
      pos 12590
      pos 13965
      pos 13980
      pos 14091
      pos 16162
    doc 1
      freq 22
      pos 1138
      pos 1361
      pos 1428
      pos 4578
      pos 4767
      pos 5890
      pos 6172
      pos 6330
      pos 6508
      pos 6530
      pos 6554
      pos 6594
      pos 6638
      pos 6657
      pos 6661
      pos 6776
      pos 6851
      pos 6967
      pos 6975
      pos 6992
      pos 8174
      pos 9416
    doc 2
      freq 5
      pos 512
      pos 4463
      pos 4520
      pos 5367
      pos 5461
    doc 3
      freq 8
      pos 794
      pos 946
      pos 1902
      pos 2511
      pos 2563
      pos 5333
      pos 5377
      pos 5395
    doc 4
      freq 8
      pos 1385
      pos 1425
      pos 2512
      pos 2938
      pos 3940
      pos 3943
      pos 4718
      pos 5666
    doc 5
      freq 3
      pos 374
      pos 2362
      pos 2409
    doc 6
      freq 7
      pos 1273
      pos 1704
      pos 1878
      pos 1940
      pos 1987
      pos 1995
      pos 2148
    doc 8
      freq 1
      pos 461
    doc 10
      freq 3
      pos 3979
      pos 8533
      pos 11257
    doc 11
      freq 3
      pos 3137
      pos 3723
      pos 5034
    doc 12
      freq 4
      pos 1032
      pos 1885
      pos 3486
      pos 3545
    doc 13
      freq 5
      pos 907
      pos 1388
      pos 1395
      pos 2991
      pos 3336
    doc 15
      freq 7
      pos 156
      pos 962
      pos 1174
      pos 1273
      pos 1791
      pos 3426
      pos 3537
    doc 16
      freq 4
      pos 1954
      pos 2322
      pos 2482
      pos 2506
    skipList 
      level 0
        skipDoc 8
        skipDocFP 1884984
        impacts 
          impact 
            freq 1
            norm 97
          impact 
            freq 7
            norm 101
          impact 
            freq 8
            norm 107
          impact 
            freq 22
            norm 113
          impact 
            freq 35
            norm 120
        impactsEnd 
  term receiver
    doc 1
      freq 1
      pos 511
    doc 4
      freq 4
      pos 2225
      pos 2845
      pos 3112
      pos 4142
    doc 5
      freq 9
      pos 1121
      pos 1179
      pos 1975
      pos 2286
      pos 2343
      pos 2422
      pos 2490
      pos 2517
      pos 2546
    doc 6
      freq 1
      pos 399
    doc 11
      freq 2
      pos 4119
      pos 6970
    doc 13
      freq 42
      pos 178
      pos 281
      pos 997
      pos 1358
      pos 1361
      pos 1382
      pos 1418
      pos 1434
      pos 1451
      pos 1519
      pos 1675
      pos 2017
      pos 2065
      pos 2208
      pos 2267
      pos 2696
      pos 3430
      pos 3440
      pos 3473
      pos 3744
      pos 4256
      pos 4270
      pos 4285
      pos 4320
      pos 4323
      pos 4350
      pos 4371
      pos 4389
      pos 4417
      pos 4483
      pos 4545
      pos 4558
      pos 4621
      pos 4637
      pos 4731
      pos 4769
      pos 4795
      pos 4828
      pos 4842
      pos 4978
      pos 6275
      pos 6610
  term receiver's
    doc 13
      freq 1
      pos 4465
  term receivers
    doc 0
      freq 1
      pos 6818
    doc 4
      freq 1
      pos 5624
    doc 5
      freq 4
      pos 118
      pos 136
      pos 497
      pos 2181
    doc 11
      freq 1
      pos 3716
    doc 13
      freq 26
      pos 966
      pos 1356
      pos 1483
      pos 1663
      pos 2058
      pos 2126
      pos 2182
      pos 2238
      pos 2961
      pos 3037
      pos 3714
      pos 3798
      pos 4045
      pos 4075
      pos 4152
      pos 4332
      pos 4523
      pos 4599
      pos 4864
      pos 4887
      pos 5072
      pos 5122
      pos 5680
      pos 5689
      pos 6320
      pos 6381
  term receives
    doc 1
      freq 3
      pos 1410
      pos 4416
      pos 7468
    doc 3
      freq 7
      pos 1400
      pos 2053
      pos 2333
      pos 2705
      pos 2740
      pos 2871
      pos 3097
    doc 4
      freq 3
      pos 3117
      pos 3671
      pos 3837
    doc 10
      freq 10
      pos 2023
      pos 3810
      pos 6409
      pos 6713
      pos 7013
      pos 10075
      pos 11191
      pos 11242
      pos 11575
      pos 11870
    doc 11
      freq 1
      pos 6544
    doc 13
      freq 1
      pos 1367
  term receiving
    doc 0
      freq 3
      pos 7643
      pos 8393
      pos 8406
    doc 1
      freq 3
      pos 6390
      pos 6462
      pos 8252
    doc 3
      freq 2
      pos 2999
      pos 5285
    doc 4
      freq 8
      pos 1643
      pos 2539
      pos 2730
      pos 3517
      pos 3693
      pos 3710
      pos 3859
      pos 4737
    doc 5
      freq 1
      pos 2415
    doc 6
      freq 1
      pos 2187
    doc 11
      freq 32
      pos 1398
      pos 3271
      pos 3479
      pos 3589
      pos 4257
      pos 4378
      pos 4418
      pos 4539
      pos 4793
      pos 5010
      pos 5101
      pos 5418
      pos 6302
      pos 6403
      pos 6750
      pos 6823
      pos 6953
      pos 7052
      pos 7057
      pos 7183
      pos 7306
      pos 7587
      pos 7692
      pos 7811
      pos 7815
      pos 7830
      pos 7919
      pos 8100
      pos 8108
      pos 8269
      pos 8405
      pos 8411
    doc 12
      freq 1
      pos 1774
    doc 13
      freq 4
      pos 3379
      pos 3731
      pos 4444
      pos 5147
    skipList 
      level 0
        skipDoc 12
        skipDocFP 1889714
        impacts 
          impact 
            freq 1
            norm 101
          impact 
            freq 2
            norm 107
          impact 
            freq 8
            norm 108
          impact 
            freq 32
            norm 114
        impactsEnd 
  term recent
    doc 9
      freq 1
      pos 905
    doc 12
      freq 1
      pos 8520
    doc 15
      freq 1
      pos 910
    doc 17
      freq 1
      pos 492
  term recently
    doc 0
      freq 1
      pos 9333
    doc 1
      freq 1
      pos 7651
    doc 2
      freq 3
      pos 1431
      pos 1660
      pos 5959
    doc 9
      freq 1
      pos 852
    doc 13
      freq 1
      pos 476
    doc 15
      freq 1
      pos 2631
  term reception
    doc 13
      freq 4
      pos 2970
      pos 3386
      pos 4585
      pos 5118
  term recipient
    doc 5
      freq 1
      pos 3380
    doc 10
      freq 2
      pos 482
      pos 4616
    doc 11
      freq 1
      pos 9005
    doc 12
      freq 3
      pos 8325
      pos 8478
      pos 8880
  term recipients
    doc 5
      freq 1
      pos 3443
    doc 10
      freq 5
      pos 1008
      pos 1009
      pos 1068
      pos 1223
      pos 4264
  term recirculation
    doc 2
      freq 1
      pos 6262
  term reclaimabl
    doc 4
      freq 4
      pos 4859
      pos 4874
      pos 4893
      pos 4947
  term reclaimed
    doc 2
      freq 1
      pos 6325
    doc 4
      freq 1
      pos 4959
  term reclassified
    doc 7
      freq 3
      pos 109
      pos 431
      pos 1398
  term reclassifying
    doc 7
      freq 1
      pos 32
  term recogniz
    doc 4
      freq 1
      pos 5636
    doc 10
      freq 3
      pos 8580
      pos 8610
      pos 8633
  term recognized
    doc 0
      freq 2
      pos 7401
      pos 7434
    doc 10
      freq 1
      pos 6075
    doc 13
      freq 1
      pos 1730
    doc 17
      freq 4
      pos 556
      pos 644
      pos 664
      pos 726
  term recognizes
    doc 17
      freq 1
      pos 616
  term recommend
    doc 12
      freq 1
      pos 5186
  term recommendation
    doc 1
      freq 1
      pos 9135
    doc 2
      freq 1
      pos 5877
    doc 7
      freq 1
      pos 2654
    doc 12
      freq 4
      pos 1112
      pos 2522
      pos 3213
      pos 8998
    doc 15
      freq 1
      pos 167
    doc 17
      freq 2
      pos 2003
      pos 2126
  term recommendations
    doc 0
      freq 1
      pos 16661
    doc 10
      freq 1
      pos 10898
    doc 12
      freq 9
      pos 91
      pos 246
      pos 319
      pos 670
      pos 685
      pos 1952
      pos 2693
      pos 3218
      pos 6748
  term recommended
    doc 0
      freq 5
      pos 964
      pos 966
      pos 16718
      pos 16808
      pos 16812
    doc 1
      freq 1
      pos 1171
    doc 2
      freq 6
      pos 1231
      pos 1610
      pos 2401
      pos 5914
      pos 6049
      pos 6295
    doc 3
      freq 4
      pos 1246
      pos 3919
      pos 5217
      pos 5252
    doc 4
      freq 5
      pos 455
      pos 1885
      pos 1956
      pos 2690
      pos 4596
    doc 5
      freq 4
      pos 1059
      pos 2027
      pos 2211
      pos 2507
    doc 6
      freq 1
      pos 1371
    doc 8
      freq 1
      pos 319
    doc 9
      freq 2
      pos 356
      pos 1237
    doc 10
      freq 7
      pos 687
      pos 689
      pos 3169
      pos 6089
      pos 8507
      pos 10959
      pos 11147
    doc 12
      freq 6
      pos 823
      pos 830
      pos 1372
      pos 2591
      pos 4087
      pos 6880
    doc 13
      freq 1
      pos 1195
    doc 15
      freq 1
      pos 3072
    doc 17
      freq 1
      pos 279
    doc 18
      freq 1
      pos 394
    skipList 
      level 0
        skipDoc 8
        skipDocFP 1893451
        impacts 
          impact 
            freq 1
            norm 97
          impact 
            freq 4
            norm 104
          impact 
            freq 6
            norm 108
        impactsEnd 
  term recommends
    doc 17
      freq 1
      pos 939
  term recomput
    doc 0
      freq 1
      pos 16072
  term recomputations
    doc 0
      freq 2
      pos 16090
      pos 16401
  term reconciled
    doc 15
      freq 2
      pos 3196
      pos 3260
  term reconsideration
    doc 7
      freq 1
      pos 1438
  term reconsidered
    doc 7
      freq 1
      pos 1362
  term reconstructed
    doc 10
      freq 1
      pos 4231
    doc 11
      freq 1
      pos 900
  term reconvergenc
    doc 6
      freq 1
      pos 2666
  term record
    doc 0
      freq 2
      pos 11705
      pos 15615
    doc 7
      freq 1
      pos 1882
    doc 10
      freq 7
      pos 444
      pos 1810
      pos 1988
      pos 3257
      pos 7474
      pos 8364
      pos 8530
    doc 11
      freq 2
      pos 2334
      pos 9260
    doc 12
      freq 27
      pos 1036
      pos 2581
      pos 2607
      pos 2908
      pos 2951
      pos 2977
      pos 2988
      pos 3099
      pos 3109
      pos 3136
      pos 4835
      pos 5032
      pos 5079
      pos 5232
      pos 5342
      pos 5513
      pos 5584
      pos 5703
      pos 5727
      pos 5756
      pos 5787
      pos 5823
      pos 5933
      pos 6023
      pos 6042
      pos 6108
      pos 8248
    doc 13
      freq 1
      pos 3609
    doc 14
      freq 4
      pos 95
      pos 303
      pos 2026
      pos 2523
    doc 18
      freq 16
      pos 190
      pos 225
      pos 743
      pos 757
      pos 766
      pos 916
      pos 933
      pos 964
      pos 976
      pos 1110
      pos 1124
      pos 1144
      pos 1151
      pos 1932
      pos 1953
      pos 1981
    skipList 
      level 0
        skipDoc 18
        skipDocFP 1895317
        impacts 
          impact 
            freq 16
            norm 97
          impact 
            freq 27
            norm 113
        impactsEnd 
  term record's
    doc 18
      freq 1
      pos 797
  term recorded
    doc 0
      freq 1
      pos 15823
    doc 6
      freq 1
      pos 2011
    doc 13
      freq 1
      pos 3004
  term recorders
    doc 13
      freq 1
      pos 930
  term recording
    doc 13
      freq 1
      pos 3047
  term records
    doc 0
      freq 3
      pos 9948
      pos 10865
      pos 12285
    doc 10
      freq 1
      pos 10631
    doc 12
      freq 73
      pos 157
      pos 166
      pos 182
      pos 278
      pos 332
      pos 603
      pos 663
      pos 753
      pos 764
      pos 775
      pos 810
      pos 827
      pos 839
      pos 855
      pos 878
      pos 919
      pos 923
      pos 931
      pos 1042
      pos 1057
      pos 1067
      pos 1077
      pos 1148
      pos 1207
      pos 1347
      pos 1701
      pos 1725
      pos 1735
      pos 1743
      pos 1768
      pos 1780
      pos 2091
      pos 2164
      pos 2515
      pos 2526
      pos 2688
      pos 2929
      pos 2944
      pos 3083
      pos 3195
      pos 3253
      pos 3310
      pos 3450
      pos 3456
      pos 3461
      pos 3469
      pos 3600
      pos 3603
      pos 3686
      pos 3791
      pos 4104
      pos 5190
      pos 5298
      pos 5474
      pos 6346
      pos 6534
      pos 6539
      pos 8201
      pos 8262
      pos 8266
      pos 8276
      pos 8280
      pos 8376
      pos 8381
      pos 8735
      pos 8747
      pos 8767
      pos 8918
      pos 9010
      pos 9163
      pos 9203
      pos 9222
      pos 9300
    doc 14
      freq 2
      pos 5441
      pos 5477
    doc 18
      freq 24
      pos 26
      pos 102
      pos 121
      pos 144
      pos 165
      pos 257
      pos 310
      pos 316
      pos 343
      pos 573
      pos 580
      pos 605
      pos 636
      pos 716
      pos 731
      pos 861
      pos 877
      pos 989
      pos 1041
      pos 1374
      pos 1646
      pos 1791
      pos 1914
      pos 2093
  term recover
    doc 10
      freq 1
      pos 12345
    doc 11
      freq 1
      pos 9762
  term recoverabl
    doc 11
      freq 2
      pos 4575
      pos 8305
  term recursiv
    doc 12
      freq 10
      pos 341
      pos 1128
      pos 3965
      pos 3981
      pos 3987
      pos 4021
      pos 4149
      pos 4186
      pos 9188
      pos 9403
    doc 15
      freq 1
      pos 1943
  term recursively
    doc 11
      freq 1
      pos 2103
  term redback
    doc 1
      freq 1
      pos 9299
  term redback.com
    doc 1
      freq 1
      pos 9310
  term redirect
    doc 0
      freq 2
      pos 16229
      pos 16412
    doc 4
      freq 2
      pos 1656
      pos 5742
    doc 10
      freq 1
      pos 2224
  term redirected
    doc 10
      freq 1
      pos 12370
    doc 11
      freq 1
      pos 9787
  term redistribution
    doc 0
      freq 3
      pos 3983
      pos 14485
      pos 14651
  term redman
    doc 11
      freq 1
      pos 9600
  term redmond
    doc 2
      freq 1
      pos 6382
  term reduc
    doc 13
      freq 2
      pos 2219
      pos 4470
    doc 18
      freq 1
      pos 1992
  term reduced
    doc 7
      freq 1
      pos 604
    doc 17
      freq 1
      pos 1637
  term reduces
    doc 10
      freq 1
      pos 9168
  term reducing
    doc 12
      freq 1
      pos 1872
    doc 13
      freq 1
      pos 4265
  term reduction
    doc 14
      freq 3
      pos 1274
      pos 1314
      pos 2865
  term redundancy
    doc 3
      freq 1
      pos 3105
    doc 15
      freq 1
      pos 2286
  term redundant
    doc 13
      freq 1
      pos 3732
  term ref
    doc 10
      freq 2
      pos 5803
      pos 5834
  term refer
    doc 0
      freq 2
      pos 52
      pos 214
    doc 1
      freq 3
      pos 69
      pos 3113
      pos 5325
    doc 3
      freq 2
      pos 63
      pos 687
    doc 4
      freq 1
      pos 65
    doc 5
      freq 1
      pos 49
    doc 8
      freq 2
      pos 1641
      pos 1659
    doc 9
      freq 1
      pos 51
    doc 10
      freq 1
      pos 54
    doc 13
      freq 1
      pos 634
    doc 15
      freq 1
      pos 531
    doc 16
      freq 2
      pos 50
      pos 862
    doc 17
      freq 1
      pos 47
    doc 18
      freq 1
      pos 56
    skipList 
      level 0
        skipDoc 10
        skipDocFP 1900250
        impacts 
          impact 
            freq 1
            norm 95
          impact 
            freq 2
            norm 97
          impact 
            freq 3
            norm 113
        impactsEnd 
  term referenc
    doc 0
      freq 72
      pos 1487
      pos 1569
      pos 1685
      pos 1734
      pos 1785
      pos 1817
      pos 1839
      pos 1868
      pos 1892
      pos 1932
      pos 1980
      pos 2009
      pos 2309
      pos 2374
      pos 2456
      pos 2517
      pos 2598
      pos 2650
      pos 2700
      pos 3126
      pos 3398
      pos 4797
      pos 4853
      pos 4954
      pos 5780
      pos 5815
      pos 6009
      pos 6071
      pos 6419
      pos 6489
      pos 6711
      pos 6770
      pos 6825
      pos 6919
      pos 6966
      pos 7006
      pos 7072
      pos 7141
      pos 7184
      pos 7369
      pos 7462
      pos 7492
      pos 7535
      pos 7562
      pos 7598
      pos 7645
      pos 7920
      pos 7957
      pos 8028
      pos 8078
      pos 8120
      pos 8486
      pos 8658
      pos 8703
      pos 8748
      pos 8788
      pos 8989
      pos 9043
      pos 9067
      pos 9111
      pos 9137
      pos 9225
      pos 9281
      pos 9311
      pos 9426
      pos 10224
      pos 10458
      pos 10494
      pos 10528
      pos 10591
      pos 10701
      pos 10785
    doc 1
      freq 4
      pos 1000
      pos 1055
      pos 1110
      pos 7831
    doc 3
      freq 6
      pos 558
      pos 641
      pos 750
      pos 857
      pos 911
      pos 5037
    doc 4
      freq 3
      pos 4923
      pos 5876
      pos 5953
    doc 6
      freq 1
      pos 260
    doc 8
      freq 8
      pos 613
      pos 629
      pos 991
      pos 1010
      pos 1285
      pos 1304
      pos 1480
      pos 1499
    doc 10
      freq 6
      pos 159
      pos 374
      pos 6167
      pos 8261
      pos 8478
      pos 12448
    doc 11
      freq 2
      pos 555
      pos 9869
    doc 13
      freq 2
      pos 1940
      pos 5321
    doc 14
      freq 2
      pos 422
      pos 658
    doc 17
      freq 1
      pos 2121
    doc 18
      freq 1
      pos 899
    skipList 
      level 0
        skipDoc 11
        skipDocFP 1901113
        impacts 
          impact 
            freq 8
            norm 97
          impact 
            freq 72
            norm 120
        impactsEnd 
  term referenced
    doc 10
      freq 1
      pos 11761
    doc 13
      freq 1
      pos 1261
    doc 17
      freq 1
      pos 212
  term references
    doc 0
      freq 4
      pos 174
      pos 178
      pos 16884
      pos 17130
    doc 1
      freq 6
      pos 401
      pos 405
      pos 2603
      pos 3837
      pos 8893
      pos 8973
    doc 2
      freq 2
      pos 160
      pos 2226
    doc 3
      freq 4
      pos 277
      pos 281
      pos 4308
      pos 4513
    doc 4
      freq 10
      pos 260
      pos 264
      pos 268
      pos 5172
      pos 5175
      pos 5302
      pos 5568
      pos 5578
      pos 5870
      pos 5944
    doc 5
      freq 6
      pos 335
      pos 339
      pos 343
      pos 4118
      pos 4121
      pos 4240
    doc 6
      freq 1
      pos 2868
    doc 7
      freq 3
      pos 153
      pos 1685
      pos 1802
    doc 8
      freq 6
      pos 169
      pos 173
      pos 177
      pos 1721
      pos 1724
      pos 1783
    doc 9
      freq 6
      pos 140
      pos 144
      pos 148
      pos 1645
      pos 1648
      pos 1736
    doc 10
      freq 6
      pos 382
      pos 385
      pos 388
      pos 13087
      pos 13089
      pos 13285
    doc 11
      freq 2
      pos 540
      pos 9618
    doc 12
      freq 6
      pos 437
      pos 441
      pos 445
      pos 6993
      pos 6996
      pos 7470
    doc 13
      freq 4
      pos 337
      pos 341
      pos 6734
      pos 6756
    doc 14
      freq 6
      pos 272
      pos 276
      pos 280
      pos 5358
      pos 5361
      pos 5467
    doc 15
      freq 2
      pos 295
      pos 3897
    doc 16
      freq 1
      pos 2521
    doc 17
      freq 3
      pos 142
      pos 1993
      pos 1996
    doc 18
      freq 2
      pos 181
      pos 2058
    skipList 
      level 0
        skipDoc 7
        skipDocFP 1903388
        impacts 
          impact 
            freq 3
            norm 100
          impact 
            freq 6
            norm 104
          impact 
            freq 10
            norm 108
        impactsEnd 
        skipDoc 15
        skipDocFP 1904101
        impacts 
          impact 
            freq 6
            norm 95
        impactsEnd 
  term referencing
    doc 13
      freq 1
      pos 661
  term referred
    doc 3
      freq 1
      pos 3934
    doc 7
      freq 1
      pos 1715
    doc 10
      freq 2
      pos 2369
      pos 4925
    doc 12
      freq 1
      pos 1933
    doc 13
      freq 1
      pos 567
  term refers
    doc 4
      freq 1
      pos 6002
    doc 6
      freq 1
      pos 1226
    doc 16
      freq 1
      pos 1013
  term refin
    doc 17
      freq 1
      pos 970
  term refined
    doc 11
      freq 1
      pos 613
  term reflect
    doc 14
      freq 1
      pos 1818
    doc 15
      freq 1
      pos 3870
  term reflected
    doc 2
      freq 1
      pos 5548
  term reflecting
    doc 7
      freq 1
      pos 86
    doc 11
      freq 1
      pos 4186
  term reflection
    doc 15
      freq 1
      pos 3594
  term reflects
    doc 12
      freq 1
      pos 5967
    doc 13
      freq 1
      pos 1150
  term refresh
    doc 12
      freq 1
      pos 3129
  term refreshed
    doc 12
      freq 2
      pos 4890
      pos 6674
  term reg
    doc 10
      freq 2
      pos 5792
      pos 5822
  term regard
    doc 1
      freq 3
      pos 3208
      pos 7993
      pos 8410
    doc 12
      freq 1
      pos 5447
    doc 17
      freq 1
      pos 182
  term regarding
    doc 0
      freq 1
      pos 17339
    doc 1
      freq 1
      pos 9720
    doc 2
      freq 1
      pos 6517
    doc 3
      freq 1
      pos 6069
    doc 4
      freq 2
      pos 5780
      pos 6224
    doc 5
      freq 1
      pos 4554
    doc 6
      freq 1
      pos 3354
    doc 7
      freq 1
      pos 3059
    doc 8
      freq 1
      pos 2276
    doc 9
      freq 1
      pos 1921
    doc 10
      freq 4
      pos 3704
      pos 9902
      pos 9954
      pos 13582
    doc 11
      freq 1
      pos 10743
    doc 12
      freq 2
      pos 6792
      pos 9593
    doc 13
      freq 2
      pos 506
      pos 7208
    doc 14
      freq 1
      pos 5674
    doc 15
      freq 1
      pos 4193
    doc 16
      freq 1
      pos 2804
    doc 17
      freq 1
      pos 2528
    doc 18
      freq 1
      pos 2316
    skipList 
      level 0
        skipDoc 7
        skipDocFP 1906699
        impacts 
          impact 
            freq 1
            norm 100
          impact 
            freq 2
            norm 108
        impactsEnd 
        skipDoc 15
        skipDocFP 1907019
        impacts 
          impact 
            freq 1
            norm 95
          impact 
            freq 2
            norm 109
          impact 
            freq 4
            norm 116
        impactsEnd 
  term regardless
    doc 1
      freq 1
      pos 4833
    doc 2
      freq 3
      pos 1814
      pos 5368
      pos 5386
    doc 3
      freq 2
      pos 1385
      pos 3887
    doc 13
      freq 1
      pos 2370
    doc 17
      freq 1
      pos 626
  term regards
    doc 9
      freq 1
      pos 487
  term regaut01
    doc 11
      freq 1
      pos 8037
  term regaut01.0ha0isndaksdj
    doc 11
      freq 1
      pos 8055
  term regauth
    doc 2
      freq 1
      pos 3435
  term regbadct
    doc 11
      freq 1
      pos 6343
  term regbadct.k345asrl3fdbv
    doc 11
      freq 1
      pos 6361
  term regenerates
    doc 3
      freq 1
      pos 1408
  term regeneration
    doc 3
      freq 1
      pos 2313
  term regescrt
    doc 11
      freq 1
      pos 8913
  term regescrt.k345asrl3fdbv
    doc 11
      freq 1
      pos 8931
  term regim
    doc 7
      freq 1
      pos 1914
  term region
    doc 0
      freq 1
      pos 16025
    doc 14
      freq 2
      pos 2580
      pos 2623
  term regional
    doc 12
      freq 1
      pos 1484
  term register
    doc 4
      freq 1
      pos 4809
    doc 10
      freq 7
      pos 1025
      pos 1081
      pos 1291
      pos 2160
      pos 3431
      pos 5886
      pos 5909
    doc 11
      freq 38
      pos 479
      pos 501
      pos 508
      pos 2304
      pos 2357
      pos 2382
      pos 2455
      pos 3216
      pos 3277
      pos 3301
      pos 3329
      pos 3352
      pos 4901
      pos 4923
      pos 6261
      pos 6344
      pos 6365
      pos 7636
      pos 7656
      pos 7897
      pos 7932
      pos 8038
      pos 8058
      pos 8649
      pos 8656
      pos 8678
      pos 8725
      pos 8754
      pos 8764
      pos 8770
      pos 8783
      pos 8815
      pos 8844
      pos 8868
      pos 8875
      pos 8888
      pos 8914
      pos 8935
  term registered
    doc 0
      freq 1
      pos 1678
    doc 5
      freq 1
      pos 3902
    doc 8
      freq 1
      pos 286
    doc 10
      freq 1
      pos 3458
    doc 11
      freq 2
      pos 7426
      pos 7564
    doc 16
      freq 1
      pos 1644
  term registers
    doc 10
      freq 4
      pos 11557
      pos 11645
      pos 11739
      pos 11852
    doc 11
      freq 1
      pos 2349
  term registrar
    doc 10
      freq 4
      pos 902
      pos 952
      pos 966
      pos 2194
    doc 11
      freq 3
      pos 7605
      pos 7951
      pos 7978
  term registrars
    doc 11
      freq 1
      pos 8008
  term registration
    doc 5
      freq 1
      pos 3700
    doc 10
      freq 5
      pos 903
      pos 940
      pos 1042
      pos 1119
      pos 9924
    doc 11
      freq 3
      pos 7969
      pos 8792
      pos 8897
    doc 17
      freq 2
      pos 348
      pos 2023
  term registrations
    doc 10
      freq 1
      pos 11076
  term registries
    doc 5
      freq 2
      pos 3706
      pos 3924
    doc 8
      freq 6
      pos 200
      pos 223
      pos 341
      pos 351
      pos 364
      pos 387
    doc 10
      freq 2
      pos 11456
      pos 11470
    doc 12
      freq 1
      pos 1486
  term registry
    doc 0
      freq 1
      pos 15828
    doc 1
      freq 3
      pos 7759
      pos 7809
      pos 7914
    doc 3
      freq 1
      pos 1989
    doc 5
      freq 5
      pos 3830
      pos 3862
      pos 3890
      pos 3991
      pos 4046
    doc 8
      freq 11
      pos 440
      pos 489
      pos 592
      pos 817
      pos 917
      pos 1146
      pos 1242
      pos 1327
      pos 1423
      pos 1517
      pos 1564
    doc 10
      freq 12
      pos 11462
      pos 11516
      pos 11619
      pos 11714
      pos 11815
      pos 11909
      pos 11936
      pos 11942
      pos 11971
      pos 12016
      pos 12024
      pos 12054
    doc 16
      freq 2
      pos 1656
      pos 1681
  term regno
    doc 3
      freq 1
      pos 4650
    doc 8
      freq 1
      pos 1853
  term regular
    doc 12
      freq 2
      pos 2359
      pos 4658
    doc 13
      freq 4
      pos 181
      pos 2428
      pos 3080
      pos 6404
  term reinald
    doc 11
      freq 1
      pos 9447
  term reissu
    doc 0
      freq 1
      pos 13364
  term reject
    doc 4
      freq 5
      pos 2199
      pos 2647
      pos 2666
      pos 5115
      pos 5703
    doc 10
      freq 2
      pos 806
      pos 3212
    doc 11
      freq 15
      pos 2515
      pos 2530
      pos 5266
      pos 5572
      pos 5738
      pos 5866
      pos 6058
      pos 6413
      pos 6523
      pos 7061
      pos 7310
      pos 7607
      pos 7834
      pos 7987
      pos 8011
  term rejected
    doc 0
      freq 1
      pos 8024
    doc 1
      freq 2
      pos 4685
      pos 7584
    doc 2
      freq 1
      pos 6288
    doc 7
      freq 1
      pos 1341
    doc 11
      freq 2
      pos 4114
      pos 6592
    doc 17
      freq 2
      pos 717
      pos 772
  term rejectedadjacencies
    doc 0
      freq 1
      pos 8030
  term rekhter
    doc 1
      freq 1
      pos 8936
    doc 8
      freq 1
      pos 2061
    doc 12
      freq 1
      pos 7016
  term rel
    doc 13
      freq 3
      pos 4745
      pos 4853
      pos 5045
  term relat
    doc 5
      freq 1
      pos 948
    doc 12
      freq 2
      pos 605
      pos 642
  term related
    doc 0
      freq 3
      pos 14433
      pos 14599
      pos 16933
    doc 1
      freq 1
      pos 986
    doc 2
      freq 2
      pos 1517
      pos 1872
    doc 3
      freq 1
      pos 4148
    doc 4
      freq 2
      pos 5320
      pos 5890
    doc 5
      freq 2
      pos 2983
      pos 3168
    doc 7
      freq 2
      pos 850
      pos 2260
    doc 9
      freq 3
      pos 164
      pos 452
      pos 543
    doc 10
      freq 3
      pos 3504
      pos 8284
      pos 13064
    doc 12
      freq 3
      pos 560
      pos 6504
      pos 6963
    doc 13
      freq 4
      pos 2802
      pos 2842
      pos 3426
      pos 5750
    doc 15
      freq 2
      pos 391
      pos 829
    skipList 
      level 0
        skipDoc 9
        skipDocFP 1913236
        impacts 
          impact 
            freq 3
            norm 95
        impactsEnd 
  term relates
    doc 13
      freq 2
      pos 5176
      pos 5639
  term relating
    doc 1
      freq 1
      pos 4603
    doc 2
      freq 7
      pos 233
      pos 1926
      pos 4849
      pos 5462
      pos 5967
      pos 6266
      pos 6280
    doc 9
      freq 1
      pos 264
    doc 12
      freq 1
      pos 717
  term relation
    doc 1
      freq 1
      pos 4205
  term relational
    doc 7
      freq 1
      pos 2593
  term relationship
    doc 1
      freq 1
      pos 8193
    doc 2
      freq 28
      pos 21
      pos 110
      pos 167
      pos 200
      pos 328
      pos 629
      pos 1079
      pos 1473
      pos 1848
      pos 2221
      pos 2458
      pos 2702
      pos 2951
      pos 3207
      pos 3448
      pos 3491
      pos 3496
      pos 3507
      pos 3874
      pos 4258
      pos 4666
      pos 4950
      pos 5027
      pos 5423
      pos 5828
      pos 6221
      pos 6335
      pos 6398
    doc 3
      freq 1
      pos 1322
    doc 5
      freq 1
      pos 2850
    doc 12
      freq 4
      pos 4284
      pos 6259
      pos 6273
      pos 6441
  term relationships
    doc 2
      freq 2
      pos 524
      pos 2241
    doc 10
      freq 1
      pos 1520
    doc 12
      freq 3
      pos 6431
      pos 6453
      pos 6484
    doc 13
      freq 2
      pos 5350
      pos 5563
  term relativ
    doc 1
      freq 1
      pos 3242
    doc 4
      freq 1
      pos 4783
    doc 5
      freq 1
      pos 1123
    doc 6
      freq 4
      pos 918
      pos 1543
      pos 1765
      pos 2275
    doc 7
      freq 1
      pos 2705
    doc 16
      freq 2
      pos 884
      pos 918
  term relatively
    doc 2
      freq 1
      pos 2171
    doc 9
      freq 1
      pos 573
    doc 11
      freq 1
      pos 1206
    doc 12
      freq 1
      pos 1612
    doc 15
      freq 1
      pos 3440
  term relaxes
    doc 18
      freq 2
      pos 679
      pos 817
  term relay
    doc 1
      freq 3
      pos 112
      pos 1614
      pos 9041
    doc 7
      freq 1
      pos 2845
    doc 8
      freq 5
      pos 632
      pos 723
      pos 788
      pos 1068
      pos 1916
    doc 15
      freq 1
      pos 1815
  term relaying
    doc 12
      freq 2
      pos 2196
      pos 2212
  term relays
    doc 15
      freq 1
      pos 2465
  term releas
    doc 1
      freq 13
      pos 360
      pos 4540
      pos 4569
      pos 4611
      pos 4950
      pos 6336
      pos 6973
      pos 6988
      pos 7329
      pos 7335
      pos 7349
      pos 7671
      pos 7699
    doc 2
      freq 1
      pos 4079
    doc 5
      freq 1
      pos 2185
    doc 13
      freq 4
      pos 231
      pos 3484
      pos 3505
      pos 3555
  term released
    doc 1
      freq 6
      pos 4584
      pos 7406
      pos 7422
      pos 7437
      pos 7544
      pos 7652
    doc 13
      freq 3
      pos 234
      pos 3487
      pos 3594
  term releases
    doc 13
      freq 1
      pos 3558
  term releasing
    doc 1
      freq 1
      pos 825
  term relevant
    doc 0
      freq 7
      pos 524
      pos 1186
      pos 1312
      pos 3333
      pos 6754
      pos 12350
      pos 15881
    doc 2
      freq 1
      pos 1063
    doc 3
      freq 1
      pos 1215
    doc 4
      freq 4
      pos 2744
      pos 2990
      pos 3226
      pos 3529
    doc 5
      freq 1
      pos 2802
    doc 12
      freq 1
      pos 9341
    doc 13
      freq 2
      pos 2783
      pos 3117
  term reliability
    doc 12
      freq 2
      pos 2747
      pos 3722
    doc 13
      freq 6
      pos 290
      pos 1128
      pos 2291
      pos 2321
      pos 4706
      pos 5099
  term reliabl
    doc 7
      freq 1
      pos 2563
    doc 13
      freq 8
      pos 297
      pos 2490
      pos 2548
      pos 2552
      pos 5041
      pos 5053
      pos 5083
      pos 6619
  term reliably
    doc 4
      freq 1
      pos 5626
    doc 12
      freq 1
      pos 1208
  term relianc
    doc 1
      freq 1
      pos 8726
    doc 3
      freq 1
      pos 4798
  term relies
    doc 1
      freq 1
      pos 8692
    doc 5
      freq 1
      pos 1563
    doc 13
      freq 1
      pos 1742
  term rely
    doc 10
      freq 1
      pos 9970
    doc 15
      freq 1
      pos 2456
  term relying
    doc 10
      freq 3
      pos 9993
      pos 10209
      pos 11032
    doc 12
      freq 1
      pos 4521
    doc 13
      freq 1
      pos 5259
    doc 17
      freq 3
      pos 114
      pos 1069
      pos 1371
  term remain
    doc 7
      freq 1
      pos 1494
    doc 12
      freq 1
      pos 1889
    doc 15
      freq 1
      pos 2410
  term remainder
    doc 1
      freq 1
      pos 1826
    doc 3
      freq 1
      pos 431
    doc 11
      freq 2
      pos 4554
      pos 8284
    doc 13
      freq 1
      pos 5774
  term remaining
    doc 0
      freq 1
      pos 11932
    doc 4
      freq 1
      pos 643
    doc 10
      freq 1
      pos 5133
    doc 11
      freq 1
      pos 754
    doc 12
      freq 1
      pos 3114
  term remaininglifetim
    doc 0
      freq 1
      pos 2821
  term remains
    doc 0
      freq 2
      pos 5078
      pos 5091
    doc 12
      freq 1
      pos 3110
  term remarks
    doc 3
      freq 1
      pos 5050
  term remember
    doc 10
      freq 2
      pos 8543
      pos 11239
    doc 12
      freq 1
      pos 8245
  term remembering
    doc 12
      freq 1
      pos 9156
  term remot
    doc 0
      freq 1
      pos 16441
    doc 1
      freq 17
      pos 500
      pos 800
      pos 2722
      pos 2964
      pos 3471
      pos 4187
      pos 4259
      pos 4336
      pos 4619
      pos 5040
      pos 5217
      pos 5778
      pos 5793
      pos 5827
      pos 5861
      pos 6241
      pos 8472
    doc 2
      freq 4
      pos 3026
      pos 3125
      pos 3142
      pos 3172
    doc 3
      freq 2
      pos 1593
      pos 1894
    doc 7
      freq 6
      pos 979
      pos 1841
      pos 2107
      pos 2431
      pos 2734
      pos 2857
    doc 10
      freq 4
      pos 1373
      pos 1392
      pos 7570
      pos 11040
  term remov
    doc 3
      freq 4
      pos 2768
      pos 5085
      pos 5099
      pos 5237
    doc 7
      freq 2
      pos 519
      pos 1260
    doc 10
      freq 6
      pos 4749
      pos 8168
      pos 8858
      pos 9243
      pos 9263
      pos 12431
    doc 11
      freq 2
      pos 832
      pos 9838
    doc 12
      freq 3
      pos 5701
      pos 5754
      pos 8554
    doc 14
      freq 10
      pos 765
      pos 796
      pos 1038
      pos 1065
      pos 1407
      pos 1456
      pos 1501
      pos 1584
      pos 1690
      pos 1717
    doc 18
      freq 2
      pos 1326
      pos 1335
  term removal
    doc 7
      freq 10
      pos 203
      pos 590
      pos 954
      pos 1304
      pos 1652
      pos 1826
      pos 2180
      pos 2538
      pos 2893
      pos 2940
  term removed
    doc 3
      freq 1
      pos 2802
    doc 4
      freq 3
      pos 4900
      pos 5582
      pos 5993
    doc 7
      freq 5
      pos 373
      pos 637
      pos 661
      pos 675
      pos 1292
    doc 11
      freq 1
      pos 2657
    doc 12
      freq 6
      pos 2953
      pos 3101
      pos 8365
      pos 8443
      pos 8460
      pos 8784
    doc 15
      freq 1
      pos 1519
  term removes
    doc 14
      freq 1
      pos 1237
  term removing
    doc 12
      freq 2
      pos 8824
      pos 9025
  term ren
    doc 11
      freq 1
      pos 10401
  term render
    doc 10
      freq 2
      pos 4636
      pos 9571
  term rendered
    doc 10
      freq 1
      pos 6200
    doc 11
      freq 6
      pos 792
      pos 1019
      pos 1107
      pos 1132
      pos 1149
      pos 1177
  term rendering
    doc 10
      freq 1
      pos 4661
    doc 11
      freq 2
      pos 1033
      pos 1119
  term rendezvous
    doc 13
      freq 2
      pos 5703
      pos 6187
  term renewal
    doc 17
      freq 1
      pos 1517
  term renewals
    doc 15
      freq 1
      pos 1500
  term renewed
    doc 12
      freq 1
      pos 4889
  term renumbered
    doc 12
      freq 1
      pos 4805
  term renumbering
    doc 12
      freq 4
      pos 421
      pos 6568
      pos 6585
      pos 7396
  term reorder
    doc 3
      freq 1
      pos 1626
    doc 6
      freq 1
      pos 2144
  term reordered
    doc 3
      freq 1
      pos 2996
  term reordering
    doc 13
      freq 1
      pos 2154
  term reorganized
    doc 4
      freq 1
      pos 5986
  term rep
    doc 13
      freq 2
      pos 6547
      pos 6632
  term repeat
    doc 11
      freq 42
      pos 1110
      pos 1114
      pos 1134
      pos 1138
      pos 1153
      pos 1159
      pos 1183
      pos 1187
      pos 2807
      pos 2811
      pos 2818
      pos 2822
      pos 2825
      pos 2829
      pos 2832
      pos 2836
      pos 2842
      pos 2846
      pos 2850
      pos 2854
      pos 2857
      pos 2861
      pos 2863
      pos 2867
      pos 2869
      pos 2873
      pos 2878
      pos 2882
      pos 2889
      pos 2893
      pos 2896
      pos 2900
      pos 2903
      pos 2907
      pos 2911
      pos 2915
      pos 3141
      pos 3145
      pos 3154
      pos 3158
      pos 4932
      pos 4936
    doc 14
      freq 1
      pos 1113
  term repeated
    doc 0
      freq 1
      pos 5339
    doc 1
      freq 1
      pos 1670
    doc 13
      freq 1
      pos 2098
    doc 16
      freq 1
      pos 551
    doc 18
      freq 1
      pos 252
  term repeatedly
    doc 14
      freq 4
      pos 712
      pos 876
      pos 1406
      pos 1583
  term repeater
    doc 2
      freq 1
      pos 2934
  term repeaters
    doc 2
      freq 1
      pos 3944
  term repeating
    doc 11
      freq 3
      pos 119
      pos 1090
      pos 1101
  term repetitions
    doc 14
      freq 2
      pos 3224
      pos 3830
  term replac
    doc 16
      freq 2
      pos 1752
      pos 1876
  term replaced
    doc 1
      freq 1
      pos 3038
    doc 4
      freq 1
      pos 5918
    doc 12
      freq 1
      pos 7905
    doc 14
      freq 1
      pos 634
    doc 15
      freq 1
      pos 2350
    doc 16
      freq 1
      pos 2141
  term replacement
    doc 10
      freq 1
      pos 9552
    doc 13
      freq 1
      pos 6558
  term replaceonlywhiledisabled
    doc 0
      freq 4
      pos 2221
      pos 5748
      pos 5894
      pos 10220
  term replay
    doc 1
      freq 1
      pos 8721
    doc 5
      freq 5
      pos 320
      pos 2152
      pos 3404
      pos 3433
      pos 3489
    doc 9
      freq 5
      pos 816
      pos 869
      pos 1263
      pos 1288
      pos 1398
    doc 10
      freq 9
      pos 5300
      pos 8258
      pos 8481
      pos 9719
      pos 9742
      pos 10201
      pos 10229
      pos 12984
      pos 12998
    doc 13
      freq 8
      pos 332
      pos 6490
      pos 6526
      pos 6599
      pos 6640
      pos 6667
      pos 6686
      pos 6717
    doc 18
      freq 1
      pos 1924
  term replayed
    doc 5
      freq 1
      pos 3480
    doc 10
      freq 3
      pos 8603
      pos 8626
      pos 8701
    doc 18
      freq 1
      pos 1916
  term replayer
    doc 10
      freq 1
      pos 9173
  term replaying
    doc 13
      freq 2
      pos 6517
      pos 6539
  term replication
    doc 7
      freq 2
      pos 705
      pos 2029
  term replies
    doc 4
      freq 6
      pos 3611
      pos 3644
      pos 3678
      pos 3695
      pos 3844
      pos 3861
    doc 5
      freq 1
      pos 2330
  term reply
    doc 4
      freq 14
      pos 219
      pos 813
      pos 1130
      pos 3715
      pos 3871
      pos 3896
      pos 3923
      pos 3960
      pos 3966
      pos 3982
      pos 4017
      pos 4193
      pos 5783
      pos 5791
    doc 12
      freq 1
      pos 1715
  term report
    doc 4
      freq 2
      pos 483
      pos 3183
    doc 6
      freq 1
      pos 767
    doc 7
      freq 1
      pos 25
  term reported
    doc 0
      freq 23
      pos 522
      pos 774
      pos 792
      pos 811
      pos 3370
      pos 3422
      pos 3479
      pos 9390
      pos 9421
      pos 9462
      pos 9543
      pos 9576
      pos 9620
      pos 9645
      pos 9728
      pos 9766
      pos 9813
      pos 9845
      pos 9876
      pos 9928
      pos 12427
      pos 12452
      pos 12489
    doc 4
      freq 2
      pos 4676
      pos 4727
  term reporting
    doc 0
      freq 1
      pos 945
    doc 1
      freq 1
      pos 810
    doc 4
      freq 1
      pos 1705
  term reports
    doc 6
      freq 1
      pos 3055
  term repository
    doc 0
      freq 1
      pos 17477
    doc 1
      freq 1
      pos 9858
    doc 2
      freq 1
      pos 6655
    doc 3
      freq 1
      pos 6207
    doc 4
      freq 1
      pos 6362
    doc 5
      freq 1
      pos 4692
    doc 6
      freq 1
      pos 3492
    doc 7
      freq 1
      pos 3197
    doc 8
      freq 1
      pos 2414
    doc 9
      freq 1
      pos 2059
    doc 10
      freq 1
      pos 13720
    doc 11
      freq 1
      pos 10881
    doc 12
      freq 1
      pos 9731
    doc 13
      freq 1
      pos 7346
    doc 14
      freq 1
      pos 5812
    doc 15
      freq 1
      pos 4331
    doc 16
      freq 1
      pos 2942
    doc 17
      freq 1
      pos 2666
    doc 18
      freq 1
      pos 2454
    skipList 
      level 0
        skipDoc 7
        skipDocFP 1926531
        impacts 
          impact 
            freq 1
            norm 100
        impactsEnd 
        skipDoc 15
        skipDocFP 1926836
        impacts 
          impact 
            freq 1
            norm 95
        impactsEnd 
  term reposting
    doc 2
      freq 1
      pos 5527
  term represent
    doc 0
      freq 1
      pos 17389
    doc 1
      freq 1
      pos 9770
    doc 2
      freq 1
      pos 6567
    doc 3
      freq 1
      pos 6119
    doc 4
      freq 1
      pos 6274
    doc 5
      freq 1
      pos 4604
    doc 6
      freq 1
      pos 3404
    doc 7
      freq 1
      pos 3109
    doc 8
      freq 1
      pos 2326
    doc 9
      freq 1
      pos 1971
    doc 10
      freq 2
      pos 12199
      pos 13632
    doc 11
      freq 4
      pos 944
      pos 1055
      pos 9751
      pos 10793
    doc 12
      freq 1
      pos 9643
    doc 13
      freq 1
      pos 7258
    doc 14
      freq 2
      pos 2364
      pos 5724
    doc 15
      freq 1
      pos 4243
    doc 16
      freq 1
      pos 2854
    doc 17
      freq 1
      pos 2578
    doc 18
      freq 2
      pos 911
      pos 2366
    skipList 
      level 0
        skipDoc 7
        skipDocFP 1927643
        impacts 
          impact 
            freq 1
            norm 100
        impactsEnd 
        skipDoc 15
        skipDocFP 1927948
        impacts 
          impact 
            freq 1
            norm 95
          impact 
            freq 2
            norm 107
          impact 
            freq 4
            norm 114
        impactsEnd 
  term representation
    doc 0
      freq 1
      pos 9031
  term represented
    doc 0
      freq 2
      pos 14411
      pos 14577
    doc 2
      freq 1
      pos 4969
    doc 12
      freq 3
      pos 594
      pos 761
      pos 772
    doc 13
      freq 1
      pos 2923
  term representing
    doc 11
      freq 6
      pos 106
      pos 111
      pos 117
      pos 875
      pos 995
      pos 1088
    doc 12
      freq 3
      pos 152
      pos 748
      pos 7208
  term represents
    doc 0
      freq 2
      pos 1531
      pos 17279
    doc 1
      freq 4
      pos 2512
      pos 2634
      pos 4130
      pos 9660
    doc 2
      freq 1
      pos 6457
    doc 3
      freq 2
      pos 1092
      pos 6009
    doc 4
      freq 1
      pos 6164
    doc 5
      freq 1
      pos 4494
    doc 6
      freq 1
      pos 3294
    doc 7
      freq 1
      pos 2999
    doc 8
      freq 1
      pos 2216
    doc 9
      freq 1
      pos 1861
    doc 10
      freq 1
      pos 13522
    doc 11
      freq 1
      pos 10683
    doc 12
      freq 1
      pos 9533
    doc 13
      freq 1
      pos 7148
    doc 14
      freq 4
      pos 2388
      pos 3220
      pos 3826
      pos 5614
    doc 15
      freq 1
      pos 4133
    doc 16
      freq 1
      pos 2744
    doc 17
      freq 1
      pos 2468
    doc 18
      freq 1
      pos 2256
    skipList 
      level 0
        skipDoc 7
        skipDocFP 1929379
        impacts 
          impact 
            freq 1
            norm 100
          impact 
            freq 2
            norm 107
          impact 
            freq 4
            norm 113
        impactsEnd 
        skipDoc 15
        skipDocFP 1929759
        impacts 
          impact 
            freq 1
            norm 95
          impact 
            freq 4
            norm 107
        impactsEnd 
  term repudiation
    doc 10
      freq 1
      pos 3253
  term req
    doc 3
      freq 2
      pos 3042
      pos 4568
    doc 13
      freq 46
      pos 3632
      pos 3671
      pos 3710
      pos 3820
      pos 3974
      pos 4019
      pos 4046
      pos 4067
      pos 4199
      pos 4215
      pos 4273
      pos 4375
      pos 4744
      pos 4852
      pos 5044
      pos 5130
      pos 5187
      pos 5253
      pos 5389
      pos 5483
      pos 5522
      pos 5539
      pos 5591
      pos 5812
      pos 5829
      pos 5855
      pos 5869
      pos 5895
      pos 5921
      pos 5963
      pos 5978
      pos 6056
      pos 6078
      pos 6107
      pos 6198
      pos 6212
      pos 6233
      pos 6252
      pos 6265
      pos 6295
      pos 6340
      pos 6406
      pos 6414
      pos 6437
      pos 6546
      pos 6631
  term request
    doc 0
      freq 3
      pos 6
      pos 5328
      pos 5343
    doc 1
      freq 6
      pos 6
      pos 4428
      pos 7710
      pos 7726
      pos 8480
      pos 8565
    doc 2
      freq 10
      pos 6
      pos 677
      pos 888
      pos 1267
      pos 1450
      pos 1490
      pos 1936
      pos 5814
      pos 5862
      pos 6001
    doc 3
      freq 2
      pos 6
      pos 2055
    doc 4
      freq 21
      pos 5
      pos 214
      pos 807
      pos 3544
      pos 3615
      pos 3648
      pos 3703
      pos 3774
      pos 3789
      pos 3815
      pos 3824
      pos 3879
      pos 3892
      pos 3905
      pos 3937
      pos 3948
      pos 3978
      pos 3995
      pos 4014
      pos 4858
      pos 5796
    doc 5
      freq 1
      pos 5
    doc 6
      freq 1
      pos 5
    doc 7
      freq 2
      pos 5
      pos 274
    doc 8
      freq 4
      pos 5
      pos 445
      pos 451
      pos 465
    doc 9
      freq 1
      pos 5
    doc 10
      freq 100
      pos 5
      pos 247
      pos 463
      pos 486
      pos 834
      pos 1026
      pos 1115
      pos 1834
      pos 1971
      pos 2025
      pos 2338
      pos 2353
      pos 2484
      pos 2534
      pos 2588
      pos 2608
      pos 3154
      pos 3179
      pos 3214
      pos 3237
      pos 3315
      pos 3328
      pos 3404
      pos 3447
      pos 3470
      pos 3510
      pos 3545
      pos 3600
      pos 3640
      pos 3650
      pos 3657
      pos 3722
      pos 3864
      pos 3973
      pos 4419
      pos 4445
      pos 4619
      pos 4673
      pos 4744
      pos 4761
      pos 4870
      pos 4962
      pos 5175
      pos 5392
      pos 5667
      pos 6306
      pos 6430
      pos 6454
      pos 6709
      pos 6715
      pos 6755
      pos 6810
      pos 6925
      pos 6945
      pos 7034
      pos 7060
      pos 7064
      pos 7082
      pos 7159
      pos 7388
      pos 7545
      pos 7575
      pos 7661
      pos 7676
      pos 7697
      pos 7894
      pos 8397
      pos 8425
      pos 8435
      pos 8449
      pos 8499
      pos 8662
      pos 8668
      pos 8682
      pos 8728
      pos 8736
      pos 8752
      pos 8879
      pos 9114
      pos 9269
      pos 9273
      pos 9325
      pos 9862
      pos 10131
      pos 10139
      pos 10337
      pos 10373
      pos 10395
      pos 10622
      pos 10662
      pos 10821
      pos 11110
      pos 11193
      pos 11244
      pos 11412
      pos 11578
      pos 11590
      pos 12279
      pos 12883
      pos 12975
    doc 11
      freq 142
      pos 6
      pos 267
      pos 292
      pos 298
      pos 307
      pos 317
      pos 325
      pos 407
      pos 414
      pos 1276
      pos 1358
      pos 1648
      pos 1866
      pos 2021
      pos 2032
      pos 2305
      pos 2338
      pos 2348
      pos 2440
      pos 2446
      pos 2522
      pos 2617
      pos 2667
      pos 2717
      pos 3217
      pos 3252
      pos 3278
      pos 3290
      pos 3311
      pos 3458
      pos 3471
      pos 3490
      pos 3563
      pos 3700
      pos 4231
      pos 4259
      pos 4266
      pos 4352
      pos 4386
      pos 4529
      pos 4548
      pos 4564
      pos 4739
      pos 4746
      pos 4795
      pos 4802
      pos 4824
      pos 4859
      pos 5086
      pos 5103
      pos 5109
      pos 5245
      pos 5249
      pos 5254
      pos 5268
      pos 5276
      pos 5297
      pos 5403
      pos 5414
      pos 5420
      pos 5427
      pos 5552
      pos 5574
      pos 5595
      pos 5601
      pos 5714
      pos 5718
      pos 5732
      pos 5740
      pos 5761
      pos 5767
      pos 5845
      pos 5854
      pos 5868
      pos 5873
      pos 5904
      pos 5909
      pos 5924
      pos 6060
      pos 6262
      pos 6304
      pos 6311
      pos 6388
      pos 6405
      pos 6415
      pos 6420
      pos 6497
      pos 6532
      pos 6564
      pos 6647
      pos 6662
      pos 6732
      pos 6752
      pos 6759
      pos 6836
      pos 7023
      pos 7059
      pos 7063
      pos 7171
      pos 7202
      pos 7277
      pos 7291
      pos 7303
      pos 7308
      pos 7341
      pos 7356
      pos 7410
      pos 7421
      pos 7434
      pos 7449
      pos 7462
      pos 7576
      pos 7600
      pos 7609
      pos 7614
      pos 7678
      pos 7694
      pos 7794
      pos 7817
      pos 7832
      pos 7898
      pos 7909
      pos 7926
      pos 7937
      pos 7989
      pos 8013
      pos 8086
      pos 8102
      pos 8110
      pos 8117
      pos 8247
      pos 8278
      pos 8294
      pos 8557
      pos 8574
      pos 8587
      pos 8657
      pos 8771
      pos 8876
      pos 8971
      pos 9008
      pos 9046
    doc 12
      freq 1
      pos 5
    doc 13
      freq 2
      pos 5
      pos 4626
    doc 14
      freq 1
      pos 5
    doc 15
      freq 1
      pos 5
    doc 16
      freq 4
      pos 5
      pos 1057
      pos 2236
      pos 2501
    doc 17
      freq 1
      pos 5
    doc 18
      freq 1
      pos 5
    skipList 
      level 0
        skipDoc 7
        skipDocFP 1931565
        impacts 
          impact 
            freq 2
            norm 100
          impact 
            freq 21
            norm 108
        impactsEnd 
        skipDoc 15
        skipDocFP 1932412
        impacts 
          impact 
            freq 1
            norm 95
          impact 
            freq 4
            norm 97
          impact 
            freq 142
            norm 114
        impactsEnd 
  term requested
    doc 2
      freq 2
      pos 1514
      pos 1879
    doc 3
      freq 3
      pos 2014
      pos 2026
      pos 2073
    doc 7
      freq 1
      pos 1591
    doc 8
      freq 7
      pos 421
      pos 428
      pos 435
      pos 914
      pos 1053
      pos 1239
      pos 1420
    doc 14
      freq 1
      pos 53
  term requesting
    doc 2
      freq 2
      pos 1424
      pos 5759
    doc 12
      freq 1
      pos 9169
    doc 13
      freq 1
      pos 5721
  term requestor
    doc 12
      freq 2
      pos 9185
      pos 9213
  term requests
    doc 0
      freq 5
      pos 45
      pos 3875
      pos 4375
      pos 11239
      pos 16164
    doc 1
      freq 1
      pos 62
    doc 2
      freq 3
      pos 655
      pos 948
      pos 1006
    doc 3
      freq 1
      pos 56
    doc 4
      freq 6
      pos 58
      pos 3673
      pos 3691
      pos 3839
      pos 3857
      pos 4963
    doc 5
      freq 1
      pos 42
    doc 8
      freq 2
      pos 46
      pos 1559
    doc 9
      freq 2
      pos 44
      pos 1548
    doc 10
      freq 46
      pos 47
      pos 115
      pos 596
      pos 918
      pos 1058
      pos 1096
      pos 1144
      pos 1226
      pos 1266
      pos 1280
      pos 1292
      pos 1433
      pos 1586
      pos 2252
      pos 2284
      pos 3488
      pos 3554
      pos 3577
      pos 3687
      pos 3732
      pos 4540
      pos 4544
      pos 4601
      pos 4606
      pos 4694
      pos 5151
      pos 7629
      pos 7984
      pos 8200
      pos 8237
      pos 8536
      pos 8694
      pos 8778
      pos 8786
      pos 8808
      pos 9079
      pos 9098
      pos 9284
      pos 10485
      pos 10507
      pos 10593
      pos 10610
      pos 11447
      pos 11464
      pos 12933
      pos 12954
    doc 11
      freq 2
      pos 7072
      pos 7438
    doc 12
      freq 2
      pos 1003
      pos 8059
    doc 13
      freq 2
      pos 5712
      pos 6066
    doc 16
      freq 1
      pos 43
    doc 17
      freq 1
      pos 40
    doc 18
      freq 1
      pos 49
    skipList 
      level 0
        skipDoc 9
        skipDocFP 1937572
        impacts 
          impact 
            freq 2
            norm 95
          impact 
            freq 6
            norm 108
        impactsEnd 
  term requir
    doc 0
      freq 3
      pos 2045
      pos 2080
      pos 2442
    doc 1
      freq 2
      pos 548
      pos 3330
    doc 2
      freq 3
      pos 2205
      pos 5974
      pos 6206
    doc 3
      freq 1
      pos 2918
    doc 4
      freq 1
      pos 5017
    doc 5
      freq 4
      pos 2136
      pos 2453
      pos 3193
      pos 3681
    doc 6
      freq 1
      pos 2545
    doc 7
      freq 2
      pos 284
      pos 1739
    doc 8
      freq 4
      pos 918
      pos 1243
      pos 1424
      pos 1565
    doc 9
      freq 1
      pos 1350
    doc 10
      freq 3
      pos 1010
      pos 4682
      pos 9927
    doc 11
      freq 10
      pos 432
      pos 434
      pos 7674
      pos 7676
      pos 7685
      pos 7687
      pos 7714
      pos 7717
      pos 7752
      pos 7756
    doc 12
      freq 6
      pos 4337
      pos 4513
      pos 5184
      pos 5874
      pos 5995
      pos 6932
    doc 13
      freq 8
      pos 2405
      pos 2719
      pos 4391
      pos 6196
      pos 6241
      pos 6351
      pos 6372
      pos 6606
    doc 14
      freq 1
      pos 5307
    doc 15
      freq 2
      pos 439
      pos 2478
    doc 16
      freq 1
      pos 1038
    doc 18
      freq 1
      pos 532
    skipList 
      level 0
        skipDoc 7
        skipDocFP 1939286
        impacts 
          impact 
            freq 2
            norm 100
          impact 
            freq 4
            norm 104
        impactsEnd 
        skipDoc 15
        skipDocFP 1939723
        impacts 
          impact 
            freq 1
            norm 95
          impact 
            freq 4
            norm 97
          impact 
            freq 8
            norm 109
          impact 
            freq 10
            norm 114
        impactsEnd 
  term required
    doc 0
      freq 54
      pos 957
      pos 3904
      pos 4416
      pos 5700
      pos 6591
      pos 10135
      pos 11434
      pos 12289
      pos 14833
      pos 14845
      pos 14857
      pos 14869
      pos 14881
      pos 14893
      pos 14905
      pos 14917
      pos 14941
      pos 14953
      pos 14965
      pos 14977
      pos 14989
      pos 15001
      pos 15013
      pos 15025
      pos 15037
      pos 15061
      pos 15073
      pos 15085
      pos 15097
      pos 15109
      pos 15121
      pos 15133
      pos 15145
      pos 15157
      pos 15169
      pos 15193
      pos 15205
      pos 15217
      pos 15229
      pos 15241
      pos 15253
      pos 15265
      pos 15277
      pos 15289
      pos 15301
      pos 15325
      pos 15337
      pos 15349
      pos 15361
      pos 15373
      pos 15385
      pos 15397
      pos 16505
      pos 17510
    doc 1
      freq 12
      pos 330
      pos 1164
      pos 1678
      pos 1704
      pos 5589
      pos 5599
      pos 6189
      pos 6297
      pos 7270
      pos 7279
      pos 7450
      pos 9891
    doc 2
      freq 9
      pos 1421
      pos 1498
      pos 1607
      pos 2056
      pos 4957
      pos 4981
      pos 5063
      pos 6187
      pos 6688
    doc 3
      freq 9
      pos 977
      pos 1025
      pos 1239
      pos 2607
      pos 3509
      pos 5608
      pos 5822
      pos 5842
      pos 6240
    doc 4
      freq 4
      pos 448
      pos 517
      pos 1477
      pos 6395
    doc 5
      freq 7
      pos 451
      pos 863
      pos 1007
      pos 1052
      pos 2239
      pos 3120
      pos 4725
    doc 6
      freq 9
      pos 349
      pos 395
      pos 477
      pos 1030
      pos 1509
      pos 1585
      pos 2204
      pos 2559
      pos 3525
    doc 7
      freq 1
      pos 3230
    doc 8
      freq 7
      pos 312
      pos 586
      pos 610
      pos 988
      pos 1282
      pos 1477
      pos 2447
    doc 9
      freq 4
      pos 349
      pos 550
      pos 642
      pos 2092
    doc 10
      freq 4
      pos 680
      pos 3868
      pos 12959
      pos 13753
    doc 11
      freq 9
      pos 402
      pos 452
      pos 1822
      pos 4104
      pos 7167
      pos 7622
      pos 8080
      pos 9056
      pos 10914
    doc 12
      freq 4
      pos 2134
      pos 4092
      pos 6004
      pos 9764
    doc 13
      freq 3
      pos 748
      pos 1188
      pos 7379
    doc 14
      freq 1
      pos 5845
    doc 15
      freq 7
      pos 942
      pos 1888
      pos 2016
      pos 3352
      pos 3395
      pos 3695
      pos 4364
    doc 16
      freq 1
      pos 2975
    doc 17
      freq 2
      pos 272
      pos 2699
    doc 18
      freq 2
      pos 387
      pos 2487
    skipList 
      level 0
        skipDoc 7
        skipDocFP 1941066
        impacts 
          impact 
            freq 1
            norm 100
          impact 
            freq 9
            norm 101
          impact 
            freq 12
            norm 113
          impact 
            freq 54
            norm 120
        impactsEnd 
        skipDoc 15
        skipDocFP 1942866
        impacts 
          impact 
            freq 4
            norm 95
          impact 
            freq 7
            norm 97
          impact 
            freq 9
            norm 114
        impactsEnd 
  term requirement
    doc 0
      freq 1
      pos 16952
    doc 1
      freq 1
      pos 8905
    doc 3
      freq 2
      pos 3008
      pos 4503
    doc 4
      freq 4
      pos 2047
      pos 5278
      pos 5841
      pos 5964
    doc 5
      freq 2
      pos 455
      pos 4133
    doc 8
      freq 1
      pos 1773
    doc 9
      freq 1
      pos 1676
    doc 10
      freq 2
      pos 705
      pos 13127
    doc 12
      freq 2
      pos 4171
      pos 8068
    doc 13
      freq 3
      pos 1693
      pos 4873
      pos 6746
    doc 15
      freq 1
      pos 3279
    doc 17
      freq 1
      pos 2038
    doc 18
      freq 6
      pos 681
      pos 819
      pos 1697
      pos 1766
      pos 1774
      pos 2137
    skipList 
      level 0
        skipDoc 10
        skipDocFP 1944393
        impacts 
          impact 
            freq 1
            norm 95
          impact 
            freq 2
            norm 104
          impact 
            freq 4
            norm 108
        impactsEnd 
  term requirements
    doc 0
      freq 6
      pos 14426
      pos 14428
      pos 14431
      pos 14592
      pos 14594
      pos 14597
    doc 1
      freq 3
      pos 220
      pos 1157
      pos 8383
    doc 2
      freq 10
      pos 2637
      pos 2671
      pos 3296
      pos 3845
      pos 5738
      pos 5804
      pos 5854
      pos 5891
      pos 5905
      pos 5947
    doc 3
      freq 7
      pos 185
      pos 273
      pos 1232
      pos 4147
      pos 4177
      pos 4427
      pos 4576
    doc 4
      freq 1
      pos 5254
    doc 5
      freq 3
      pos 885
      pos 924
      pos 933
    doc 6
      freq 2
      pos 2525
      pos 2556
    doc 7
      freq 1
      pos 2711
    doc 8
      freq 2
      pos 114
      pos 305
    doc 9
      freq 4
      pos 661
      pos 1030
      pos 1053
      pos 1694
    doc 10
      freq 4
      pos 380
      pos 12840
      pos 12843
      pos 13373
    doc 11
      freq 1
      pos 750
    doc 12
      freq 1
      pos 737
    doc 13
      freq 44
      pos 31
      pos 77
      pos 100
      pos 124
      pos 238
      pos 242
      pos 354
      pos 758
      pos 1031
      pos 1113
      pos 1140
      pos 1461
      pos 1528
      pos 1820
      pos 1920
      pos 2172
      pos 2564
      pos 2624
      pos 2847
      pos 2935
      pos 3302
      pos 3620
      pos 3623
      pos 3663
      pos 3874
      pos 3891
      pos 3913
      pos 3934
      pos 3964
      pos 4299
      pos 4674
      pos 4698
      pos 4881
      pos 5019
      pos 5186
      pos 5381
      pos 5643
      pos 5731
      pos 5781
      pos 6010
      pos 6332
      pos 6654
      pos 6944
      pos 7084
    doc 15
      freq 1
      pos 3300
    doc 17
      freq 4
      pos 328
      pos 960
      pos 973
      pos 1038
    doc 18
      freq 1
      pos 2075
    skipList 
      level 0
        skipDoc 7
        skipDocFP 1945404
        impacts 
          impact 
            freq 1
            norm 100
          impact 
            freq 2
            norm 101
          impact 
            freq 3
            norm 104
          impact 
            freq 7
            norm 107
          impact 
            freq 10
            norm 108
        impactsEnd 
        skipDoc 17
        skipDocFP 1946084
        impacts 
          impact 
            freq 4
            norm 95
          impact 
            freq 44
            norm 109
        impactsEnd 
  term requires
    doc 0
      freq 8
      pos 14457
      pos 14481
      pos 14517
      pos 14623
      pos 14647
      pos 14683
      pos 14707
      pos 14731
    doc 1
      freq 1
      pos 2931
    doc 3
      freq 1
      pos 2929
    doc 4
      freq 1
      pos 4481
    doc 5
      freq 3
      pos 1152
      pos 2145
      pos 3697
    doc 6
      freq 1
      pos 2823
    doc 7
      freq 1
      pos 1437
    doc 9
      freq 2
      pos 212
      pos 246
    doc 10
      freq 4
      pos 1730
      pos 4326
      pos 9355
      pos 9550
    doc 12
      freq 3
      pos 4541
      pos 5542
      pos 9094
    doc 13
      freq 1
      pos 1796
    doc 14
      freq 2
      pos 1212
      pos 5283
    doc 18
      freq 3
      pos 352
      pos 1640
      pos 1656
    skipList 
      level 0
        skipDoc 9
        skipDocFP 1947827
        impacts 
          impact 
            freq 2
            norm 95
          impact 
            freq 3
            norm 104
          impact 
            freq 8
            norm 120
        impactsEnd 
  term requiring
    doc 2
      freq 7
      pos 1482
      pos 1717
      pos 2084
      pos 4689
      pos 4711
      pos 4723
      pos 5238
    doc 12
      freq 2
      pos 1514
      pos 8865
    doc 13
      freq 3
      pos 163
      pos 2004
      pos 4059
  term requisit
    doc 10
      freq 1
      pos 3124
  term rescorl
    doc 2
      freq 1
      pos 6367
    doc 10
      freq 2
      pos 12110
      pos 13275
    doc 11
      freq 1
      pos 9502
  term research
    doc 9
      freq 2
      pos 10
      pos 1768
    doc 13
      freq 2
      pos 7010
      pos 7026
  term resend
    doc 13
      freq 1
      pos 5006
  term resends
    doc 10
      freq 2
      pos 6432
      pos 7036
  term reservation
    doc 6
      freq 1
      pos 2882
  term reserved
    doc 3
      freq 2
      pos 3671
      pos 3699
    doc 4
      freq 7
      pos 795
      pos 824
      pos 839
      pos 887
      pos 5135
      pos 5164
      pos 5720
    doc 5
      freq 2
      pos 3812
      pos 4028
    doc 8
      freq 6
      pos 273
      pos 370
      pos 559
      pos 890
      pos 1215
      pos 1396
    doc 11
      freq 1
      pos 3946
  term reserves
    doc 2
      freq 1
      pos 3801
  term resettingtimer
    doc 0
      freq 8
      pos 2104
      pos 2568
      pos 2691
      pos 6917
      pos 6964
      pos 7047
      pos 7139
      pos 7182
  term resides
    doc 1
      freq 1
      pos 3191
  term resilienc
    doc 13
      freq 1
      pos 2152
    doc 15
      freq 1
      pos 2827
  term resilient
    doc 13
      freq 1
      pos 2090
  term resistant
    doc 17
      freq 1
      pos 1477
    doc 18
      freq 1
      pos 1745
  term resnick
    doc 2
      freq 1
      pos 6369
    doc 11
      freq 1
      pos 9620
    doc 16
      freq 16
      pos 4
      pos 162
      pos 528
      pos 903
      pos 1308
      pos 1563
      pos 1682
      pos 1850
      pos 2108
      pos 2245
      pos 2507
      pos 2560
      pos 2636
      pos 2652
      pos 2676
      pos 3007
  term resolution
    doc 2
      freq 3
      pos 2979
      pos 6084
      pos 6145
    doc 6
      freq 1
      pos 1365
    doc 12
      freq 2
      pos 7751
      pos 7866
    doc 13
      freq 1
      pos 5451
  term resolv
    doc 4
      freq 1
      pos 2473
    doc 11
      freq 1
      pos 752
  term resolv.conf
    doc 15
      freq 2
      pos 1049
      pos 3108
  term resolved
    doc 2
      freq 1
      pos 1795
  term resolver
    doc 12
      freq 10
      pos 106
      pos 322
      pos 2903
      pos 2935
      pos 3221
      pos 4083
      pos 4132
      pos 4180
      pos 4188
      pos 9180
    doc 14
      freq 1
      pos 2151
  term resolvers
    doc 12
      freq 14
      pos 229
      pos 342
      pos 349
      pos 694
      pos 1630
      pos 1906
      pos 1917
      pos 2972
      pos 3966
      pos 3982
      pos 4140
      pos 4150
      pos 8014
      pos 8992
    doc 18
      freq 1
      pos 1768
  term resolving
    doc 12
      freq 1
      pos 4981
  term resourc
    doc 0
      freq 1
      pos 4922
    doc 6
      freq 1
      pos 2881
    doc 7
      freq 2
      pos 2612
      pos 2707
    doc 10
      freq 4
      pos 5582
      pos 5628
      pos 11686
      pos 13348
    doc 11
      freq 2
      pos 5807
      pos 9684
    doc 12
      freq 6
      pos 602
      pos 1056
      pos 1066
      pos 2606
      pos 8247
      pos 8766
    doc 13
      freq 1
      pos 4490
    doc 14
      freq 4
      pos 94
      pos 302
      pos 2025
      pos 5440
    doc 15
      freq 1
      pos 2787
    doc 16
      freq 1
      pos 321
    doc 18
      freq 3
      pos 101
      pos 730
      pos 2092
    skipList 
      level 0
        skipDoc 14
        skipDocFP 1951936
        impacts 
          impact 
            freq 2
            norm 100
          impact 
            freq 4
            norm 107
          impact 
            freq 6
            norm 113
        impactsEnd 
  term resources
    doc 0
      freq 1
      pos 2905
    doc 6
      freq 2
      pos 2519
      pos 2590
    doc 13
      freq 7
      pos 638
      pos 2227
      pos 4081
      pos 5663
      pos 5707
      pos 6436
      pos 6450
  term resp
    doc 16
      freq 5
      pos 1452
      pos 1497
      pos 1516
      pos 1519
      pos 1546
  term respect
    doc 0
      freq 1
      pos 17407
    doc 1
      freq 2
      pos 4795
      pos 9788
    doc 2
      freq 2
      pos 5741
      pos 6585
    doc 3
      freq 1
      pos 6137
    doc 4
      freq 1
      pos 6292
    doc 5
      freq 1
      pos 4622
    doc 6
      freq 1
      pos 3422
    doc 7
      freq 1
      pos 3127
    doc 8
      freq 1
      pos 2344
    doc 9
      freq 1
      pos 1989
    doc 10
      freq 2
      pos 9408
      pos 13650
    doc 11
      freq 1
      pos 10811
    doc 12
      freq 2
      pos 8408
      pos 9661
    doc 13
      freq 1
      pos 7276
    doc 14
      freq 1
      pos 5742
    doc 15
      freq 1
      pos 4261
    doc 16
      freq 1
      pos 2872
    doc 17
      freq 1
      pos 2596
    doc 18
      freq 1
      pos 2384
    skipList 
      level 0
        skipDoc 7
        skipDocFP 1953228
        impacts 
          impact 
            freq 1
            norm 100
          impact 
            freq 2
            norm 108
        impactsEnd 
        skipDoc 15
        skipDocFP 1953563
        impacts 
          impact 
            freq 1
            norm 95
          impact 
            freq 2
            norm 113
        impactsEnd 
  term respectiv
    doc 1
      freq 2
      pos 3561
      pos 5175
    doc 3
      freq 2
      pos 1325
      pos 1830
    doc 5
      freq 3
      pos 2938
      pos 3308
      pos 3825
    doc 8
      freq 1
      pos 202
    doc 13
      freq 1
      pos 6384
    doc 15
      freq 1
      pos 3776
  term respectively
    doc 1
      freq 2
      pos 3547
      pos 3938
    doc 10
      freq 1
      pos 12309
    doc 12
      freq 1
      pos 708
    doc 14
      freq 1
      pos 682
    doc 15
      freq 1
      pos 373
    doc 16
      freq 1
      pos 665
    doc 18
      freq 2
      pos 1239
      pos 1878
  term respects
    doc 10
      freq 1
      pos 1405
  term respond
    doc 1
      freq 1
      pos 6944
    doc 10
      freq 1
      pos 4525
    doc 11
      freq 16
      pos 4261
      pos 4381
      pos 4543
      pos 4797
      pos 5422
      pos 6306
      pos 6659
      pos 6754
      pos 6827
      pos 7197
      pos 7696
      pos 8112
      pos 8273
      pos 8577
      pos 9010
      pos 9041
    doc 13
      freq 1
      pos 4451
  term responded
    doc 2
      freq 1
      pos 556
    doc 12
      freq 1
      pos 1794
  term responder
    doc 4
      freq 2
      pos 3668
      pos 3834
    doc 5
      freq 4
      pos 2282
      pos 2334
      pos 2398
      pos 2418
  term responding
    doc 11
      freq 1
      pos 7729
    doc 12
      freq 1
      pos 8176
  term respons
    doc 1
      freq 1
      pos 7722
    doc 4
      freq 9
      pos 1113
      pos 1142
      pos 2247
      pos 2508
      pos 2571
      pos 2868
      pos 2934
      pos 3874
      pos 3901
    doc 6
      freq 1
      pos 2789
    doc 10
      freq 37
      pos 319
      pos 327
      pos 334
      pos 342
      pos 2592
      pos 3094
      pos 3681
      pos 3770
      pos 3893
      pos 4061
      pos 4150
      pos 4240
      pos 4511
      pos 4518
      pos 6419
      pos 7023
      pos 11453
      pos 11553
      pos 11561
      pos 11600
      pos 11616
      pos 11626
      pos 11641
      pos 11649
      pos 11695
      pos 11711
      pos 11721
      pos 11735
      pos 11743
      pos 11796
      pos 11812
      pos 11822
      pos 11848
      pos 11856
      pos 11890
      pos 11906
      pos 11916
    doc 11
      freq 32
      pos 275
      pos 382
      pos 464
      pos 3921
      pos 3957
      pos 3967
      pos 4085
      pos 4947
      pos 4954
      pos 5012
      pos 6421
      pos 6533
      pos 6825
      pos 6940
      pos 6943
      pos 6946
      pos 6955
      pos 7067
      pos 7318
      pos 7479
      pos 7615
      pos 7702
      pos 7958
      pos 7984
      pos 8372
      pos 8383
      pos 8423
      pos 8431
      pos 8682
      pos 8975
      pos 8997
      pos 9023
    doc 12
      freq 10
      pos 1776
      pos 3484
      pos 3538
      pos 8330
      pos 8482
      pos 8497
      pos 8569
      pos 8578
      pos 8885
      pos 9118
    doc 13
      freq 1
      pos 2597
    doc 14
      freq 3
      pos 1787
      pos 2824
      pos 2867
    doc 15
      freq 4
      pos 960
      pos 1093
      pos 1473
      pos 1960
    doc 16
      freq 23
      pos 789
      pos 1197
      pos 1203
      pos 1205
      pos 1220
      pos 1227
      pos 1238
      pos 1249
      pos 1252
      pos 1287
      pos 1322
      pos 1325
      pos 1396
      pos 1501
      pos 1504
      pos 1507
      pos 1511
      pos 1553
      pos 1920
      pos 1928
      pos 2272
      pos 2491
      pos 2494
    doc 18
      freq 2
      pos 945
      pos 1360
    skipList 
      level 0
        skipDoc 14
        skipDocFP 1955877
        impacts 
          impact 
            freq 1
            norm 101
          impact 
            freq 3
            norm 107
          impact 
            freq 9
            norm 108
          impact 
            freq 10
            norm 113
          impact 
            freq 32
            norm 114
          impact 
            freq 37
            norm 116
        impactsEnd 
  term responses
    doc 10
      freq 4
      pos 1592
      pos 8876
      pos 8928
      pos 9007
    doc 11
      freq 1
      pos 8449
    doc 12
      freq 4
      pos 914
      pos 8084
      pos 8337
      pos 8711
    doc 14
      freq 1
      pos 2429
    doc 15
      freq 7
      pos 218
      pos 860
      pos 922
      pos 1307
      pos 1311
      pos 1892
      pos 3046
    doc 16
      freq 4
      pos 523
      pos 590
      pos 593
      pos 1170
  term responsibility
    doc 0
      freq 1
      pos 16827
    doc 2
      freq 1
      pos 3990
    doc 3
      freq 1
      pos 2323
  term responsibl
    doc 10
      freq 6
      pos 2411
      pos 2434
      pos 2456
      pos 2472
      pos 3629
      pos 7738
    doc 16
      freq 2
      pos 1061
      pos 1145
  term rest
    doc 3
      freq 1
      pos 3692
  term restart
    doc 1
      freq 1
      pos 7680
  term restarting
    doc 1
      freq 1
      pos 7457
  term reston
    doc 1
      freq 1
      pos 9347
    doc 3
      freq 2
      pos 4850
      pos 4908
  term restored
    doc 0
      freq 1
      pos 16301
  term restrict
    doc 14
      freq 1
      pos 2095
  term restricted
    doc 0
      freq 2
      pos 2032
      pos 2067
    doc 12
      freq 1
      pos 2407
    doc 13
      freq 1
      pos 6155
    doc 14
      freq 3
      pos 485
      pos 2276
      pos 2411
  term restriction
    doc 14
      freq 2
      pos 194
      pos 2348
  term restrictions
    doc 0
      freq 1
      pos 17241
    doc 1
      freq 1
      pos 9622
    doc 2
      freq 1
      pos 6419
    doc 3
      freq 1
      pos 5971
    doc 4
      freq 2
      pos 2037
      pos 6126
    doc 5
      freq 1
      pos 4456
    doc 6
      freq 1
      pos 3251
    doc 7
      freq 1
      pos 2961
    doc 8
      freq 1
      pos 2178
    doc 9
      freq 1
      pos 1823
    doc 10
      freq 1
      pos 13484
    doc 11
      freq 1
      pos 10645
    doc 12
      freq 1
      pos 9495
    doc 13
      freq 3
      pos 1319
      pos 1784
      pos 7110
    doc 14
      freq 1
      pos 5576
    doc 15
      freq 1
      pos 4095
    doc 16
      freq 1
      pos 2706
    doc 17
      freq 1
      pos 2430
    doc 18
      freq 1
      pos 2218
    skipList 
      level 0
        skipDoc 7
        skipDocFP 1959934
        impacts 
          impact 
            freq 1
            norm 100
          impact 
            freq 2
            norm 108
        impactsEnd 
        skipDoc 15
        skipDocFP 1960254
        impacts 
          impact 
            freq 1
            norm 95
          impact 
            freq 3
            norm 109
        impactsEnd 
  term result
    doc 0
      freq 3
      pos 6800
      pos 6895
      pos 17442
    doc 1
      freq 6
      pos 1253
      pos 4919
      pos 4982
      pos 7578
      pos 8821
      pos 9823
    doc 2
      freq 12
      pos 1198
      pos 2183
      pos 3695
      pos 4184
      pos 4651
      pos 4820
      pos 5051
      pos 5657
      pos 6182
      pos 6277
      pos 6311
      pos 6620
    doc 3
      freq 1
      pos 6172
    doc 4
      freq 2
      pos 1641
      pos 6327
    doc 5
      freq 1
      pos 4657
    doc 6
      freq 3
      pos 2111
      pos 2393
      pos 3457
    doc 7
      freq 1
      pos 3162
    doc 8
      freq 1
      pos 2379
    doc 9
      freq 2
      pos 262
      pos 2024
    doc 10
      freq 9
      pos 5546
      pos 6422
      pos 7026
      pos 8593
      pos 8949
      pos 9485
      pos 10003
      pos 10496
      pos 13685
    doc 11
      freq 2
      pos 4635
      pos 10846
    doc 12
      freq 6
      pos 3558
      pos 3706
      pos 6606
      pos 9216
      pos 9381
      pos 9696
    doc 13
      freq 3
      pos 5062
      pos 6591
      pos 7311
    doc 14
      freq 6
      pos 1147
      pos 1769
      pos 2233
      pos 2303
      pos 2444
      pos 5777
    doc 15
      freq 1
      pos 4296
    doc 16
      freq 2
      pos 596
      pos 2907
    doc 17
      freq 1
      pos 2631
    doc 18
      freq 1
      pos 2419
    skipList 
      level 0
        skipDoc 7
        skipDocFP 1961149
        impacts 
          impact 
            freq 1
            norm 100
          impact 
            freq 3
            norm 101
          impact 
            freq 12
            norm 108
        impactsEnd 
        skipDoc 15
        skipDocFP 1961770
        impacts 
          impact 
            freq 2
            norm 95
          impact 
            freq 6
            norm 107
          impact 
            freq 9
            norm 116
        impactsEnd 
  term resultant
    doc 6
      freq 1
      pos 2327
  term resulted
    doc 2
      freq 1
      pos 5140
    doc 4
      freq 1
      pos 1039
  term resulting
    doc 3
      freq 4
      pos 2166
      pos 2193
      pos 2203
      pos 2304
    doc 4
      freq 2
      pos 307
      pos 1867
    doc 6
      freq 1
      pos 2678
    doc 10
      freq 3
      pos 6543
      pos 7246
      pos 8023
    doc 16
      freq 2
      pos 1331
      pos 1400
  term results
    doc 1
      freq 2
      pos 5865
      pos 5924
    doc 6
      freq 1
      pos 2167
    doc 7
      freq 6
      pos 94
      pos 415
      pos 685
      pos 1482
      pos 1519
      pos 1539
    doc 10
      freq 3
      pos 3835
      pos 5511
      pos 5528
    doc 14
      freq 3
      pos 1270
      pos 1310
      pos 2173
  term retain
    doc 0
      freq 1
      pos 17254
    doc 1
      freq 1
      pos 9635
    doc 2
      freq 1
      pos 6432
    doc 3
      freq 1
      pos 5984
    doc 4
      freq 1
      pos 6139
    doc 5
      freq 1
      pos 4469
    doc 6
      freq 1
      pos 3269
    doc 7
      freq 1
      pos 2974
    doc 8
      freq 1
      pos 2191
    doc 9
      freq 1
      pos 1836
    doc 10
      freq 1
      pos 13497
    doc 11
      freq 1
      pos 10658
    doc 12
      freq 1
      pos 9508
    doc 13
      freq 1
      pos 7123
    doc 14
      freq 1
      pos 5589
    doc 15
      freq 1
      pos 4108
    doc 16
      freq 1
      pos 2719
    doc 17
      freq 1
      pos 2443
    doc 18
      freq 1
      pos 2231
    skipList 
      level 0
        skipDoc 7
        skipDocFP 1963910
        impacts 
          impact 
            freq 1
            norm 100
        impactsEnd 
        skipDoc 15
        skipDocFP 1964215
        impacts 
          impact 
            freq 1
            norm 95
        impactsEnd 
  term retained
    doc 6
      freq 1
      pos 1969
    doc 12
      freq 1
      pos 8505
  term retaining
    doc 10
      freq 1
      pos 3946
  term retargeted
    doc 10
      freq 2
      pos 3472
      pos 3512
  term retargeting
    doc 10
      freq 9
      pos 206
      pos 3394
      pos 3395
      pos 3410
      pos 3440
      pos 3584
      pos 3663
      pos 3715
      pos 13365
  term retention
    doc 1
      freq 1
      pos 1853
    doc 3
      freq 1
      pos 4655
    doc 8
      freq 2
      pos 1080
      pos 1858
  term retir
    doc 12
      freq 1
      pos 1841
  term retired
    doc 7
      freq 3
      pos 190
      pos 353
      pos 381
  term retiring
    doc 7
      freq 1
      pos 233
  term retriev
    doc 4
      freq 1
      pos 1530
    doc 13
      freq 3
      pos 2698
      pos 2711
      pos 6071
    doc 15
      freq 1
      pos 375
    doc 18
      freq 1
      pos 262
  term retrieval
    doc 11
      freq 2
      pos 8789
      pos 8894
    doc 13
      freq 3
      pos 1707
      pos 2295
      pos 2365
  term retrieved
    doc 0
      freq 2
      pos 5541
      pos 5559
    doc 13
      freq 2
      pos 773
      pos 5692
  term retrieving
    doc 13
      freq 2
      pos 4908
      pos 6366
  term retrofitted
    doc 15
      freq 2
      pos 2633
      pos 3165
  term retry
    doc 11
      freq 2
      pos 4976
      pos 5051
    doc 12
      freq 4
      pos 8332
      pos 8484
      pos 8867
      pos 8887
  term return
    doc 0
      freq 2
      pos 3124
      pos 3296
    doc 9
      freq 3
      pos 181
      pos 768
      pos 1233
    doc 10
      freq 6
      pos 1019
      pos 1064
      pos 1127
      pos 1147
      pos 1160
      pos 3091
    doc 11
      freq 3
      pos 4628
      pos 5105
      pos 7473
    doc 12
      freq 8
      pos 946
      pos 1170
      pos 1380
      pos 3133
      pos 8270
      pos 8732
      pos 8744
      pos 9371
    doc 13
      freq 1
      pos 4643
    doc 15
      freq 2
      pos 2303
      pos 2736
    doc 16
      freq 7
      pos 1052
      pos 1194
      pos 1236
      pos 1363
      pos 1393
      pos 1949
      pos 2317
    doc 18
      freq 2
      pos 255
      pos 1890
    skipList 
      level 0
        skipDoc 16
        skipDocFP 1966451
        impacts 
          impact 
            freq 3
            norm 95
          impact 
            freq 7
            norm 99
          impact 
            freq 8
            norm 113
        impactsEnd 
  term returned
    doc 0
      freq 5
      pos 3870
      pos 4370
      pos 6704
      pos 6763
      pos 11234
    doc 4
      freq 1
      pos 3952
    doc 10
      freq 2
      pos 4064
      pos 4243
    doc 12
      freq 8
      pos 2690
      pos 3008
      pos 3684
      pos 3793
      pos 8951
      pos 9261
      pos 9304
      pos 9388
    doc 15
      freq 3
      pos 2032
      pos 2227
      pos 2874
    doc 16
      freq 5
      pos 784
      pos 1255
      pos 1328
      pos 1923
      pos 2487
    doc 18
      freq 3
      pos 718
      pos 1113
      pos 1127
  term returning
    doc 12
      freq 4
      pos 1799
      pos 8861
      pos 8871
      pos 9220
    doc 15
      freq 1
      pos 3624
  term returns
    doc 11
      freq 1
      pos 916
    doc 14
      freq 3
      pos 437
      pos 469
      pos 1165
    doc 15
      freq 2
      pos 694
      pos 701
    doc 16
      freq 2
      pos 517
      pos 2269
    doc 18
      freq 1
      pos 1848
  term reused
    doc 5
      freq 1
      pos 3277
    doc 10
      freq 1
      pos 2663
  term reusing
    doc 10
      freq 1
      pos 8753
  term rev
    doc 2
      freq 4
      pos 5330
      pos 5431
      pos 5456
      pos 5545
  term reveal
    doc 5
      freq 1
      pos 3611
    doc 13
      freq 1
      pos 6033
  term revealing
    doc 14
      freq 1
      pos 2459
  term revers
    doc 2
      freq 1
      pos 6083
    doc 12
      freq 47
      pos 118
      pos 372
      pos 379
      pos 705
      pos 767
      pos 819
      pos 833
      pos 1308
      pos 1422
      pos 1450
      pos 1471
      pos 1575
      pos 4261
      pos 4921
      pos 4926
      pos 4949
      pos 4958
      pos 4964
      pos 5031
      pos 5053
      pos 5073
      pos 5122
      pos 5167
      pos 5188
      pos 5264
      pos 5291
      pos 5435
      pos 5472
      pos 5575
      pos 5652
      pos 5664
      pos 5932
      pos 5956
      pos 6021
      pos 6100
      pos 6128
      pos 6227
      pos 6292
      pos 6303
      pos 6339
      pos 6379
      pos 6397
      pos 6456
      pos 6948
      pos 7717
      pos 7943
      pos 8005
    doc 18
      freq 1
      pos 1835
  term reversed
    doc 1
      freq 2
      pos 4774
      pos 4793
  term reverses
    doc 12
      freq 2
      pos 5326
      pos 5530
  term revert
    doc 1
      freq 2
      pos 5805
      pos 5910
  term review
    doc 2
      freq 34
      pos 132
      pos 136
      pos 140
      pos 144
      pos 148
      pos 980
      pos 987
      pos 999
      pos 1172
      pos 1221
      pos 1278
      pos 1337
      pos 1369
      pos 1426
      pos 1434
      pos 1478
      pos 1511
      pos 1698
      pos 1723
      pos 1737
      pos 1765
      pos 1968
      pos 2019
      pos 2039
      pos 2089
      pos 2101
      pos 2185
      pos 2208
      pos 4271
      pos 4305
      pos 4505
      pos 5512
      pos 6184
      pos 6208
    doc 4
      freq 2
      pos 4943
      pos 5510
    doc 5
      freq 2
      pos 3792
      pos 4008
    doc 6
      freq 1
      pos 126
    doc 7
      freq 9
      pos 79
      pos 169
      pos 180
      pos 405
      pos 629
      pos 631
      pos 1327
      pos 1444
      pos 1462
    doc 8
      freq 10
      pos 122
      pos 253
      pos 378
      pos 392
      pos 464
      pos 527
      pos 857
      pos 1183
      pos 1364
      pos 1553
    doc 10
      freq 1
      pos 762
    doc 11
      freq 1
      pos 9426
    doc 14
      freq 1
      pos 5354
    doc 18
      freq 3
      pos 367
      pos 494
      pos 2052
    skipList 
      level 0
        skipDoc 11
        skipDocFP 1969863
        impacts 
          impact 
            freq 10
            norm 97
          impact 
            freq 34
            norm 108
        impactsEnd 
  term review.txt
    doc 2
      freq 1
      pos 2285
  term reviewed
    doc 2
      freq 5
      pos 1250
      pos 1785
      pos 4245
      pos 4589
      pos 5260
    doc 7
      freq 1
      pos 1352
    doc 9
      freq 1
      pos 1628
    doc 11
      freq 1
      pos 9463
  term reviewers
    doc 2
      freq 1
      pos 3359
  term reviewing
    doc 6
      freq 1
      pos 3166
    doc 8
      freq 1
      pos 443
  term reviews
    doc 5
      freq 1
      pos 4100
    doc 10
      freq 1
      pos 12175
    doc 12
      freq 1
      pos 6838
  term revis
    doc 7
      freq 3
      pos 407
      pos 647
      pos 1533
  term revised
    doc 2
      freq 8
      pos 286
      pos 2201
      pos 5175
      pos 5220
      pos 5253
      pos 5289
      pos 5301
      pos 6202
    doc 4
      freq 1
      pos 5823
    doc 7
      freq 1
      pos 1855
    doc 11
      freq 1
      pos 2662
    doc 15
      freq 1
      pos 335
  term revision
    doc 0
      freq 1
      pos 1234
    doc 2
      freq 4
      pos 3993
      pos 5057
      pos 5278
      pos 5354
    doc 7
      freq 1
      pos 1810
  term revisions
    doc 2
      freq 1
      pos 5247
  term revocation
    doc 10
      freq 3
      pos 3958
      pos 4100
      pos 13245
    doc 17
      freq 7
      pos 337
      pos 1426
      pos 1433
      pos 1512
      pos 1580
      pos 1623
      pos 2065
  term revoked
    doc 10
      freq 1
      pos 4141
    doc 17
      freq 1
      pos 1454
  term rewrit
    doc 3
      freq 4
      pos 1483
      pos 2058
      pos 2712
      pos 2766
  term rewriting
    doc 2
      freq 1
      pos 4724
    doc 3
      freq 1
      pos 2041
  term rey
    doc 4
      freq 1
      pos 6080
  term rfc
    doc 0
      freq 134
      pos 185
      pos 219
      pos 285
      pos 290
      pos 296
      pos 339
      pos 486
      pos 660
      pos 821
      pos 985
      pos 993
      pos 1154
      pos 1202
      pos 1224
      pos 1228
      pos 1245
      pos 1400
      pos 1612
      pos 1690
      pos 1778
      pos 1790
      pos 1822
      pos 1861
      pos 1873
      pos 1919
      pos 2095
      pos 2327
      pos 2537
      pos 2718
      pos 2897
      pos 3085
      pos 3246
      pos 3457
      pos 3669
      pos 3804
      pos 4015
      pos 4200
      pos 4403
      pos 4546
      pos 4703
      pos 4819
      pos 5041
      pos 5235
      pos 5472
      pos 5586
      pos 5768
      pos 5949
      pos 6010
      pos 6072
      pos 6177
      pos 6342
      pos 6432
      pos 6652
      pos 6906
      pos 7085
      pos 7249
      pos 7350
      pos 7512
      pos 7677
      pos 7816
      pos 7950
      pos 8134
      pos 8329
      pos 8419
      pos 8638
      pos 8826
      pos 8926
      pos 9044
      pos 9078
      pos 9243
      pos 9437
      pos 9593
      pos 9737
      pos 9903
      pos 10043
      pos 10169
      pos 10383
      pos 10582
      pos 10808
      pos 11020
      pos 11094
      pos 11302
      pos 11483
      pos 11641
      pos 11772
      pos 11878
      pos 12049
      pos 12176
      pos 12312
      pos 12465
      pos 12637
      pos 12785
      pos 12990
      pos 13181
      pos 13340
      pos 13540
      pos 13734
      pos 13924
      pos 14135
      pos 14322
      pos 14499
      pos 14665
      pos 14803
      pos 14923
      pos 15050
      pos 15177
      pos 15307
      pos 15418
      pos 15489
      pos 15560
      pos 15638
      pos 15722
      pos 15799
      pos 16131
      pos 16320
      pos 16472
      pos 16605
      pos 16843
      pos 16956
      pos 16976
      pos 16990
      pos 17010
      pos 17035
      pos 17056
      pos 17074
      pos 17092
      pos 17101
      pos 17124
      pos 17143
      pos 17168
      pos 17191
      pos 17216
      pos 17411
      pos 17530
    doc 1
      freq 46
      pos 204
      pos 427
      pos 835
      pos 1064
      pos 1372
      pos 1865
      pos 2225
      pos 2421
      pos 2695
      pos 3054
      pos 3424
      pos 3609
      pos 3906
      pos 4243
      pos 4637
      pos 5017
      pos 5296
      pos 5688
      pos 6023
      pos 6364
      pos 6759
      pos 7197
      pos 7639
      pos 7768
      pos 7818
      pos 7889
      pos 7925
      pos 8237
      pos 8422
      pos 8634
      pos 8705
      pos 8907
      pos 8925
      pos 8949
      pos 8967
      pos 9020
      pos 9117
      pos 9161
      pos 9177
      pos 9224
      pos 9331
      pos 9401
      pos 9496
      pos 9597
      pos 9792
      pos 9911
    doc 2
      freq 58
      pos 195
      pos 624
      pos 1074
      pos 1468
      pos 1843
      pos 2216
      pos 2244
      pos 2268
      pos 2319
      pos 2453
      pos 2697
      pos 2912
      pos 2938
      pos 2946
      pos 2965
      pos 2981
      pos 3012
      pos 3033
      pos 3042
      pos 3061
      pos 3085
      pos 3099
      pos 3114
      pos 3131
      pos 3154
      pos 3181
      pos 3194
      pos 3202
      pos 3223
      pos 3241
      pos 3259
      pos 3279
      pos 3300
      pos 3323
      pos 3347
      pos 3365
      pos 3381
      pos 3406
      pos 3443
      pos 3486
      pos 3564
      pos 3869
      pos 4253
      pos 4648
      pos 4661
      pos 4781
      pos 5022
      pos 5418
      pos 5498
      pos 5510
      pos 5578
      pos 5823
      pos 5896
      pos 6216
      pos 6330
      pos 6393
      pos 6589
      pos 6708
    doc 3
      freq 38
      pos 167
      pos 332
      pos 441
      pos 579
      pos 759
      pos 1038
      pos 1260
      pos 1424
      pos 1777
      pos 2116
      pos 2427
      pos 2822
      pos 3206
      pos 3615
      pos 4009
      pos 4297
      pos 4332
      pos 4350
      pos 4380
      pos 4397
      pos 4507
      pos 4528
      pos 4558
      pos 4585
      pos 4623
      pos 4692
      pos 4709
      pos 4728
      pos 4739
      pos 4832
      pos 4936
      pos 5001
      pos 5197
      pos 5587
      pos 5788
      pos 5944
      pos 6141
      pos 6260
    doc 4
      freq 63
      pos 140
      pos 277
      pos 299
      pos 421
      pos 432
      pos 434
      pos 438
      pos 440
      pos 469
      pos 741
      pos 1010
      pos 1358
      pos 1367
      pos 1754
      pos 2076
      pos 2313
      pos 2717
      pos 2963
      pos 3200
      pos 3436
      pos 3626
      pos 3798
      pos 4088
      pos 4498
      pos 4816
      pos 4822
      pos 4884
      pos 4903
      pos 4993
      pos 4996
      pos 5082
      pos 5155
      pos 5188
      pos 5208
      pos 5212
      pos 5222
      pos 5226
      pos 5246
      pos 5250
      pos 5262
      pos 5266
      pos 5282
      pos 5286
      pos 5296
      pos 5303
      pos 5324
      pos 5342
      pos 5361
      pos 5378
      pos 5389
      pos 5400
      pos 5417
      pos 5434
      pos 5530
      pos 5542
      pos 5550
      pos 5815
      pos 5878
      pos 5900
      pos 6034
      pos 6100
      pos 6296
      pos 6415
    doc 5
      freq 29
      pos 248
      pos 351
      pos 787
      pos 1073
      pos 1144
      pos 1475
      pos 1742
      pos 2045
      pos 2356
      pos 2553
      pos 2734
      pos 3048
      pos 3358
      pos 3659
      pos 3911
      pos 4111
      pos 4137
      pos 4158
      pos 4178
      pos 4206
      pos 4234
      pos 4297
      pos 4311
      pos 4337
      pos 4347
      pos 4372
      pos 4432
      pos 4626
      pos 4745
    doc 6
      freq 23
      pos 64
      pos 120
      pos 143
      pos 170
      pos 287
      pos 740
      pos 1130
      pos 1611
      pos 2026
      pos 2340
      pos 2756
      pos 2889
      pos 2900
      pos 2947
      pos 2962
      pos 2982
      pos 3024
      pos 3033
      pos 3058
      pos 3082
      pos 3223
      pos 3426
      pos 3545
    doc 7
      freq 189
      pos 159
      pos 162
      pos 200
      pos 256
      pos 272
      pos 277
      pos 298
      pos 587
      pos 672
      pos 686
      pos 694
      pos 703
      pos 718
      pos 724
      pos 737
      pos 745
      pos 751
      pos 759
      pos 774
      pos 778
      pos 784
      pos 789
      pos 794
      pos 809
      pos 823
      pos 837
      pos 852
      pos 863
      pos 873
      pos 892
      pos 901
      pos 911
      pos 919
      pos 923
      pos 951
      pos 957
      pos 966
      pos 972
      pos 983
      pos 993
      pos 1003
      pos 1012
      pos 1020
      pos 1031
      pos 1037
      pos 1046
      pos 1053
      pos 1067
      pos 1077
      pos 1086
      pos 1095
      pos 1102
      pos 1109
      pos 1115
      pos 1123
      pos 1135
      pos 1301
      pos 1512
      pos 1525
      pos 1588
      pos 1649
      pos 1814
      pos 1823
      pos 1833
      pos 1839
      pos 1848
      pos 1853
      pos 1860
      pos 1865
      pos 1871
      pos 1877
      pos 1884
      pos 1891
      pos 1897
      pos 1904
      pos 1910
      pos 1916
      pos 1925
      pos 1932
      pos 1938
      pos 1944
      pos 1950
      pos 1957
      pos 1968
      pos 1982
      pos 1990
      pos 1999
      pos 2005
      pos 2018
      pos 2027
      pos 2042
      pos 2055
      pos 2061
      pos 2074
      pos 2081
      pos 2089
      pos 2098
      pos 2104
      pos 2111
      pos 2121
      pos 2129
      pos 2138
      pos 2149
      pos 2164
      pos 2168
      pos 2177
      pos 2183
      pos 2189
      pos 2194
      pos 2199
      pos 2204
      pos 2219
      pos 2233
      pos 2247
      pos 2262
      pos 2273
      pos 2283
      pos 2301
      pos 2318
      pos 2337
      pos 2356
      pos 2365
      pos 2375
      pos 2383
      pos 2387
      pos 2401
      pos 2410
      pos 2418
      pos 2424
      pos 2435
      pos 2448
      pos 2458
      pos 2471
      pos 2481
      pos 2490
      pos 2499
      pos 2504
      pos 2509
      pos 2518
      pos 2524
      pos 2535
      pos 2541
      pos 2546
      pos 2552
      pos 2560
      pos 2565
      pos 2576
      pos 2582
      pos 2591
      pos 2599
      pos 2604
      pos 2609
      pos 2615
      pos 2623
      pos 2630
      pos 2641
      pos 2651
      pos 2661
      pos 2670
      pos 2679
      pos 2688
      pos 2695
      pos 2703
      pos 2709
      pos 2717
      pos 2724
      pos 2731
      pos 2741
      pos 2750
      pos 2757
      pos 2768
      pos 2774
      pos 2782
      pos 2791
      pos 2797
      pos 2805
      pos 2815
      pos 2823
      pos 2832
      pos 2840
      pos 2846
      pos 2851
      pos 2861
      pos 2868
      pos 2880
      pos 2890
      pos 2937
      pos 3131
      pos 3250
    doc 8
      freq 17
      pos 185
      pos 472
      pos 797
      pos 1124
      pos 1438
      pos 1668
      pos 1742
      pos 1758
      pos 1777
      pos 1808
      pos 1929
      pos 2005
      pos 2074
      pos 2123
      pos 2152
      pos 2348
      pos 2467
    doc 9
      freq 18
      pos 230
      pos 370
      pos 522
      pos 593
      pos 813
      pos 934
      pos 1078
      pos 1095
      pos 1370
      pos 1661
      pos 1680
      pos 1699
      pos 1716
      pos 1725
      pos 1758
      pos 1796
      pos 1993
      pos 2112
    doc 10
      freq 94
      pos 172
      pos 396
      pos 422
      pos 455
      pos 511
      pos 700
      pos 787
      pos 880
      pos 1250
      pos 1341
      pos 1701
      pos 2088
      pos 2416
      pos 2514
      pos 2623
      pos 2969
      pos 3373
      pos 3785
      pos 4115
      pos 4184
      pos 4480
      pos 4595
      pos 4800
      pos 4939
      pos 5077
      pos 5079
      pos 5098
      pos 5321
      pos 5399
      pos 5470
      pos 5521
      pos 5532
      pos 5619
      pos 5764
      pos 5780
      pos 6054
      pos 6272
      pos 6477
      pos 6525
      pos 6780
      pos 6966
      pos 7227
      pos 7270
      pos 7464
      pos 7600
      pos 7787
      pos 7982
      pos 8032
      pos 8038
      pos 8187
      pos 8298
      pos 8466
      pos 8486
      pos 8986
      pos 9228
      pos 9476
      pos 9941
      pos 10331
      pos 10480
      pos 10604
      pos 10759
      pos 10765
      pos 10787
      pos 10989
      pos 10996
      pos 11204
      pos 11542
      pos 11837
      pos 12094
      pos 12162
      pos 12385
      pos 12532
      pos 12696
      pos 12831
      pos 13081
      pos 13112
      pos 13131
      pos 13147
      pos 13164
      pos 13180
      pos 13196
      pos 13208
      pos 13222
      pos 13249
      pos 13270
      pos 13280
      pos 13308
      pos 13321
      pos 13331
      pos 13358
      pos 13399
      pos 13460
      pos 13654
      pos 13773
    doc 11
      freq 68
      pos 189
      pos 492
      pos 527
      pos 819
      pos 1045
      pos 1252
      pos 1438
      pos 1572
      pos 1896
      pos 2110
      pos 2290
      pos 2542
      pos 2625
      pos 2659
      pos 2783
      pos 3051
      pos 3318
      pos 3441
      pos 3686
      pos 3882
      pos 3983
      pos 4169
      pos 4409
      pos 4652
      pos 4890
      pos 4984
      pos 5068
      pos 5235
      pos 5392
      pos 5540
      pos 5700
      pos 5832
      pos 6020
      pos 6122
      pos 6244
      pos 6480
      pos 6716
      pos 6930
      pos 7027
      pos 7092
      pos 7140
      pos 7268
      pos 7546
      pos 7780
      pos 8027
      pos 8224
      pos 8456
      pos 8640
      pos 8859
      pos 8958
      pos 9148
      pos 9157
      pos 9168
      pos 9203
      pos 9413
      pos 9625
      pos 9651
      pos 9670
      pos 9691
      pos 9720
      pos 9858
      pos 10024
      pos 10214
      pos 10423
      pos 10516
      pos 10619
      pos 10815
      pos 10934
    doc 12
      freq 65
      pos 237
      pos 499
      pos 863
      pos 1221
      pos 1329
      pos 1558
      pos 1943
      pos 2277
      pos 2648
      pos 3020
      pos 3384
      pos 3813
      pos 4195
      pos 4560
      pos 5011
      pos 5420
      pos 5856
      pos 6246
      pos 6639
      pos 6984
      pos 7007
      pos 7030
      pos 7045
      pos 7068
      pos 7082
      pos 7094
      pos 7105
      pos 7119
      pos 7137
      pos 7154
      pos 7167
      pos 7192
      pos 7221
      pos 7231
      pos 7255
      pos 7276
      pos 7294
      pos 7310
      pos 7324
      pos 7341
      pos 7364
      pos 7382
      pos 7404
      pos 7419
      pos 7434
      pos 7450
      pos 7460
      pos 7484
      pos 7507
      pos 7523
      pos 7540
      pos 7551
      pos 7567
      pos 7585
      pos 7603
      pos 7620
      pos 7704
      pos 7884
      pos 8237
      pos 8634
      pos 9046
      pos 9418
      pos 9469
      pos 9665
      pos 9784
    doc 13
      freq 33
      pos 122
      pos 352
      pos 756
      pos 1138
      pos 1209
      pos 1459
      pos 1818
      pos 2170
      pos 2562
      pos 2933
      pos 3300
      pos 3661
      pos 3962
      pos 4297
      pos 4672
      pos 5017
      pos 5379
      pos 5729
      pos 6008
      pos 6330
      pos 6652
      pos 6750
      pos 6767
      pos 6782
      pos 6850
      pos 6876
      pos 6902
      pos 6916
      pos 6932
      pos 6942
      pos 7082
      pos 7280
      pos 7399
    doc 14
      freq 30
      pos 215
      pos 558
      pos 842
      pos 1219
      pos 1548
      pos 1869
      pos 2159
      pos 2550
      pos 2904
      pos 3257
      pos 3541
      pos 3839
      pos 4135
      pos 4221
      pos 4286
      pos 4408
      pos 4502
      pos 4584
      pos 4962
      pos 5190
      pos 5372
      pos 5386
      pos 5401
      pos 5424
      pos 5447
      pos 5456
      pos 5483
      pos 5549
      pos 5746
      pos 5865
    doc 15
      freq 23
      pos 111
      pos 124
      pos 192
      pos 303
      pos 633
      pos 1023
      pos 1391
      pos 1751
      pos 2146
      pos 2592
      pos 3004
      pos 3405
      pos 3800
      pos 3905
      pos 3919
      pos 3933
      pos 3958
      pos 3974
      pos 3996
      pos 4006
      pos 4069
      pos 4265
      pos 4384
    doc 16
      freq 24
      pos 167
      pos 533
      pos 908
      pos 1078
      pos 1313
      pos 1568
      pos 1654
      pos 1687
      pos 1855
      pos 2113
      pos 2250
      pos 2512
      pos 2531
      pos 2541
      pos 2555
      pos 2565
      pos 2587
      pos 2601
      pos 2617
      pos 2632
      pos 2641
      pos 2681
      pos 2876
      pos 2995
    doc 17
      freq 16
      pos 155
      pos 514
      pos 814
      pos 1052
      pos 1398
      pos 1847
      pos 2042
      pos 2069
      pos 2086
      pos 2112
      pos 2150
      pos 2202
      pos 2319
      pos 2405
      pos 2600
      pos 2719
    doc 18
      freq 19
      pos 114
      pos 245
      pos 408
      pos 621
      pos 673
      pos 686
      pos 1029
      pos 1173
      pos 1209
      pos 1384
      pos 1811
      pos 2076
      pos 2099
      pos 2122
      pos 2141
      pos 2151
      pos 2194
      pos 2388
      pos 2507
    skipList 
      level 0
        skipDoc 7
        skipDocFP 1973002
        impacts 
          impact 
            freq 189
            norm 100
        impactsEnd 
        skipDoc 15
        skipDocFP 1981875
        impacts 
          impact 
            freq 18
            norm 95
          impact 
            freq 23
            norm 104
          impact 
            freq 30
            norm 107
          impact 
            freq 33
            norm 109
          impact 
            freq 65
            norm 113
          impact 
            freq 68
            norm 114
          impact 
            freq 94
            norm 116
        impactsEnd 
  term rfc1034
    doc 12
      freq 2
      pos 6997
      pos 8230
    doc 14
      freq 5
      pos 675
      pos 1884
      pos 2089
      pos 2355
      pos 5362
  term rfc1035
    doc 14
      freq 2
      pos 2951
      pos 5376
  term rfc1195
    doc 0
      freq 2
      pos 341
      pos 16960
  term rfc1305
    doc 5
      freq 2
      pos 2206
      pos 4287
  term rfc1493
    doc 2
      freq 4
      pos 243
      pos 2896
      pos 3558
      pos 4728
  term rfc2108
    doc 2
      freq 3
      pos 257
      pos 2916
      pos 3930
  term rfc2119
    doc 0
      freq 2
      pos 987
      pos 16941
    doc 1
      freq 2
      pos 1185
      pos 8894
    doc 3
      freq 2
      pos 1262
      pos 4492
    doc 5
      freq 2
      pos 1075
      pos 4122
    doc 8
      freq 2
      pos 333
      pos 1762
    doc 17
      freq 2
      pos 293
      pos 2027
  term rfc2136
    doc 12
      freq 2
      pos 4414
      pos 7011
  term rfc2181
    doc 12
      freq 6
      pos 7034
      pos 7629
      pos 8301
      pos 8444
      pos 8670
      pos 9359
    doc 14
      freq 2
      pos 2008
      pos 5390
  term rfc2182
    doc 12
      freq 2
      pos 3216
      pos 7049
  term rfc2277
    doc 1
      freq 2
      pos 6284
      pos 9165
    doc 8
      freq 2
      pos 1037
      pos 1746
  term rfc2284
    doc 2
      freq 4
      pos 2954
      pos 4867
      pos 4999
      pos 5138
  term rfc2327
    doc 5
      freq 2
      pos 2905
      pos 4301
  term rfc2390
    doc 2
      freq 2
      pos 2969
      pos 6124
  term rfc2434
    doc 5
      freq 2
      pos 3980
      pos 4141
    doc 8
      freq 17
      pos 244
      pos 257
      pos 396
      pos 531
      pos 551
      pos 580
      pos 861
      pos 881
      pos 911
      pos 1187
      pos 1207
      pos 1236
      pos 1368
      pos 1388
      pos 1417
      pos 1557
      pos 1725
  term rfc2462
    doc 12
      freq 2
      pos 4248
      pos 7072
  term rfc2571
    doc 0
      freq 1
      pos 1049
  term rfc2578
    doc 0
      freq 4
      pos 287
      pos 395
      pos 1033
      pos 17039
  term rfc2579
    doc 0
      freq 4
      pos 292
      pos 392
      pos 1019
      pos 17060
  term rfc2580
    doc 0
      freq 4
      pos 298
      pos 398
      pos 1043
      pos 17078
  term rfc2671
    doc 12
      freq 2
      pos 7086
      pos 9328
  term rfc2674
    doc 2
      freq 5
      pos 252
      pos 2985
      pos 4321
      pos 4697
      pos 4714
  term rfc2766
    doc 12
      freq 2
      pos 6531
      pos 7471
  term rfc2782
    doc 12
      freq 2
      pos 2092
      pos 7488
    doc 14
      freq 2
      pos 2526
      pos 5405
  term rfc2821
    doc 12
      freq 2
      pos 2945
      pos 7098
  term rfc2822
    doc 11
      freq 2
      pos 6140
      pos 9619
  term rfc2826
    doc 12
      freq 2
      pos 891
      pos 7511
  term rfc2863
    doc 0
      freq 3
      pos 408
      pos 1060
      pos 16980
  term rfc2865
    doc 2
      freq 5
      pos 2168
      pos 3016
      pos 5070
      pos 6140
      pos 6194
  term rfc2866
    doc 2
      freq 2
      pos 3037
      pos 5071
  term rfc2867
    doc 2
      freq 2
      pos 3046
      pos 5072
  term rfc2868
    doc 2
      freq 2
      pos 3065
      pos 5073
  term rfc2869
    doc 2
      freq 4
      pos 3089
      pos 4869
      pos 5047
      pos 5074
  term rfc2973
    doc 0
      freq 2
      pos 437
      pos 17131
  term rfc2992
    doc 3
      freq 2
      pos 3305
      pos 4681
  term rfc3007
    doc 12
      freq 4
      pos 4415
      pos 4458
      pos 5522
      pos 7109
  term rfc3032
    doc 1
      freq 2
      pos 2000
      pos 8929
    doc 8
      freq 2
      pos 695
      pos 2054
  term rfc3036
    doc 1
      freq 5
      pos 739
      pos 2066
      pos 2250
      pos 4695
      pos 8911
  term rfc3041
    doc 12
      freq 3
      pos 1331
      pos 1395
      pos 7123
  term rfc3056
    doc 12
      freq 2
      pos 1400
      pos 7141
  term rfc3152
    doc 12
      freq 2
      pos 796
      pos 7158
  term rfc3162
    doc 2
      freq 2
      pos 3103
      pos 5076
  term rfc3261
    doc 5
      freq 2
      pos 2916
      pos 4315
    doc 11
      freq 7
      pos 592
      pos 2176
      pos 3258
      pos 6645
      pos 8408
      pos 9325
      pos 9629
  term rfc3264
    doc 11
      freq 2
      pos 607
      pos 9655
  term rfc3280
    doc 17
      freq 6
      pos 188
      pos 933
      pos 1096
      pos 2046
      pos 2204
      pos 2363
  term rfc3281
    doc 17
      freq 3
      pos 259
      pos 1903
      pos 2073
  term rfc3289
    doc 0
      freq 3
      pos 405
      pos 1055
      pos 16994
  term rfc3291
    doc 0
      freq 1
      pos 1068
  term rfc3315
    doc 12
      freq 2
      pos 3918
      pos 7171
    doc 15
      freq 1
      pos 2568
  term rfc3363
    doc 12
      freq 3
      pos 794
      pos 824
      pos 7196
  term rfc3364
    doc 12
      freq 2
      pos 856
      pos 7239
  term rfc3373
    doc 0
      freq 2
      pos 450
      pos 17147
  term rfc3410
    doc 0
      freq 3
      pos 221
      pos 16732
      pos 17172
  term rfc3411
    doc 0
      freq 2
      pos 402
      pos 17014
  term rfc3575
    doc 2
      freq 4
      pos 1560
      pos 2198
      pos 3118
      pos 6200
  term rfc3579
    doc 2
      freq 7
      pos 295
      pos 3135
      pos 5058
      pos 5257
      pos 5299
      pos 5467
      pos 5503
  term rfc3580
    doc 2
      freq 6
      pos 284
      pos 3158
      pos 4886
      pos 5101
      pos 5295
      pos 5488
  term rfc3596
    doc 12
      freq 3
      pos 786
      pos 1048
      pos 7259
  term rfc3621
    doc 2
      freq 3
      pos 278
      pos 3185
      pos 4008
  term rfc3635
    doc 2
      freq 3
      pos 263
      pos 3210
      pos 3996
  term rfc3636
    doc 2
      freq 3
      pos 267
      pos 3227
      pos 3966
  term rfc3637
    doc 2
      freq 3
      pos 273
      pos 3245
      pos 4002
  term rfc3646
    doc 12
      freq 2
      pos 3991
      pos 7280
  term rfc3704
    doc 12
      freq 3
      pos 5546
      pos 6892
      pos 7527
  term rfc3711
    doc 5
      freq 4
      pos 503
      pos 2768
      pos 2799
      pos 4353
  term rfc3736
    doc 12
      freq 2
      pos 4005
      pos 7298
  term rfc3748
    doc 2
      freq 11
      pos 292
      pos 1386
      pos 2068
      pos 2114
      pos 3263
      pos 5223
      pos 5308
      pos 5320
      pos 5464
      pos 5601
      pos 5844
  term rfc3830
    doc 5
      freq 21
      pos 596
      pos 625
      pos 657
      pos 766
      pos 1517
      pos 1571
      pos 1637
      pos 1682
      pos 2006
      pos 2213
      pos 2311
      pos 2387
      pos 2820
      pos 2858
      pos 3711
      pos 3773
      pos 3833
      pos 3865
      pos 3893
      pos 3904
      pos 4162
  term rfc3879
    doc 12
      freq 3
      pos 1284
      pos 7314
      pos 7912
  term rfc3901
    doc 12
      freq 4
      pos 1138
      pos 3172
      pos 4147
      pos 7328
  term rfc3972
    doc 12
      freq 2
      pos 5872
      pos 7544
  term rfc3985
    doc 1
      freq 4
      pos 1006
      pos 2041
      pos 3067
      pos 9147
    doc 3
      freq 6
      pos 424
      pos 535
      pos 564
      pos 3230
      pos 4083
      pos 4514
  term rfc3986
    doc 11
      freq 2
      pos 2096
      pos 9674
  term rfc4001
    doc 0
      freq 2
      pos 413
      pos 17108
  term rfc4017
    doc 2
      freq 3
      pos 2117
      pos 3283
      pos 5957
  term rfc4025
    doc 12
      freq 2
      pos 5174
      pos 7555
  term rfc4026
    doc 3
      freq 2
      pos 1228
      pos 4696
  term rfc4034
    doc 14
      freq 4
      pos 381
      pos 1842
      pos 1908
      pos 5428
  term rfc4035
    doc 18
      freq 1
      pos 824
  term rfc4038
    doc 12
      freq 2
      pos 3753
      pos 7345
  term rfc4074
    doc 12
      freq 2
      pos 1692
      pos 7368
  term rfc4082
    doc 5
      freq 7
      pos 473
      pos 509
      pos 955
      pos 2247
      pos 2774
      pos 2791
      pos 4182
  term rfc4118
    doc 2
      freq 2
      pos 1770
      pos 3304
  term rfc4137
    doc 2
      freq 8
      pos 302
      pos 2078
      pos 3327
      pos 5218
      pos 5310
      pos 5322
      pos 5465
      pos 5603
  term rfc4181
    doc 2
      freq 2
      pos 1247
      pos 3351
  term rfc4188
    doc 2
      freq 2
      pos 244
      pos 3369
  term rfc4192
    doc 12
      freq 3
      pos 4908
      pos 6587
      pos 7386
  term rfc4193
    doc 12
      freq 3
      pos 7408
      pos 7903
      pos 8072
  term rfc4213
    doc 12
      freq 2
      pos 6761
      pos 7571
  term rfc4215
    doc 12
      freq 2
      pos 7589
      pos 9246
  term rfc4291
    doc 12
      freq 2
      pos 1260
      pos 7423
  term rfc4339
    doc 12
      freq 2
      pos 4045
      pos 7438
  term rfc4363
    doc 2
      freq 2
      pos 253
      pos 3385
  term rfc4380
    doc 12
      freq 2
      pos 1583
      pos 7607
  term rfc4383
    doc 5
      freq 14
      pos 498
      pos 560
      pos 873
      pos 967
      pos 996
      pos 1082
      pos 1109
      pos 1115
      pos 1206
      pos 1893
      pos 2763
      pos 2796
      pos 2947
      pos 4210
  term rfc4385
    doc 8
      freq 3
      pos 1643
      pos 1661
      pos 2099
  term rfc4447
    doc 1
      freq 8
      pos 7837
      pos 7843
      pos 7849
      pos 7856
      pos 7861
      pos 7867
      pos 7873
      pos 7881
  term rfc4470
    doc 14
      freq 3
      pos 314
      pos 1863
      pos 5468
  term rfcs
    doc 0
      freq 1
      pos 16949
    doc 1
      freq 1
      pos 8902
    doc 2
      freq 3
      pos 1358
      pos 3762
      pos 5566
    doc 3
      freq 1
      pos 4500
    doc 4
      freq 1
      pos 5275
    doc 5
      freq 2
      pos 4130
      pos 4155
    doc 6
      freq 1
      pos 95
    doc 7
      freq 6
      pos 475
      pos 632
      pos 650
      pos 1615
      pos 1714
      pos 1832
    doc 8
      freq 2
      pos 1739
      pos 1770
    doc 9
      freq 1
      pos 1673
    doc 10
      freq 4
      pos 5750
      pos 12003
      pos 12087
      pos 13124
    doc 11
      freq 1
      pos 805
    doc 13
      freq 1
      pos 6743
    doc 17
      freq 1
      pos 2035
    doc 18
      freq 1
      pos 2134
    skipList 
      level 0
        skipDoc 7
        skipDocFP 1998560
        impacts 
          impact 
            freq 6
            norm 100
        impactsEnd 
  term rhviudavky2x5dzuvoaod8veyqutofj6qxvktcw0dakdrbdob3cik3h
    doc 10
      freq 1
      pos 12516
  term rhwhr7mkhtu3k
    doc 10
      freq 1
      pos 6857
  term rich
    doc 13
      freq 1
      pos 2050
  term richard
    doc 11
      freq 1
      pos 9452
  term richardson
    doc 12
      freq 1
      pos 7556
  term rid
    doc 7
      freq 1
      pos 21
    doc 16
      freq 2
      pos 439
      pos 454
  term right
    doc 1
      freq 1
      pos 8780
    doc 2
      freq 1
      pos 3803
    doc 9
      freq 2
      pos 188
      pos 280
    doc 12
      freq 1
      pos 8941
    doc 14
      freq 11
      pos 779
      pos 814
      pos 1006
      pos 1043
      pos 1484
      pos 1514
      pos 1658
      pos 1695
      pos 3270
      pos 4432
      pos 4991
  term rights
    doc 0
      freq 11
      pos 16872
      pos 17238
      pos 17257
      pos 17319
      pos 17348
      pos 17351
      pos 17379
      pos 17401
      pos 17409
      pos 17460
      pos 17502
    doc 1
      freq 10
      pos 9619
      pos 9638
      pos 9700
      pos 9729
      pos 9732
      pos 9760
      pos 9782
      pos 9790
      pos 9841
      pos 9883
    doc 2
      freq 10
      pos 6416
      pos 6435
      pos 6497
      pos 6526
      pos 6529
      pos 6557
      pos 6579
      pos 6587
      pos 6638
      pos 6680
    doc 3
      freq 10
      pos 5968
      pos 5987
      pos 6049
      pos 6078
      pos 6081
      pos 6109
      pos 6131
      pos 6139
      pos 6190
      pos 6232
    doc 4
      freq 11
      pos 5291
      pos 6123
      pos 6142
      pos 6204
      pos 6233
      pos 6236
      pos 6264
      pos 6286
      pos 6294
      pos 6345
      pos 6387
    doc 5
      freq 10
      pos 4453
      pos 4472
      pos 4534
      pos 4563
      pos 4566
      pos 4594
      pos 4616
      pos 4624
      pos 4675
      pos 4717
    doc 6
      freq 10
      pos 3248
      pos 3272
      pos 3334
      pos 3363
      pos 3366
      pos 3394
      pos 3416
      pos 3424
      pos 3475
      pos 3517
    doc 7
      freq 10
      pos 2958
      pos 2977
      pos 3039
      pos 3068
      pos 3071
      pos 3099
      pos 3121
      pos 3129
      pos 3180
      pos 3222
    doc 8
      freq 10
      pos 2175
      pos 2194
      pos 2256
      pos 2285
      pos 2288
      pos 2316
      pos 2338
      pos 2346
      pos 2397
      pos 2439
    doc 9
      freq 10
      pos 1820
      pos 1839
      pos 1901
      pos 1930
      pos 1933
      pos 1961
      pos 1983
      pos 1991
      pos 2042
      pos 2084
    doc 10
      freq 10
      pos 13481
      pos 13500
      pos 13562
      pos 13591
      pos 13594
      pos 13622
      pos 13644
      pos 13652
      pos 13703
      pos 13745
    doc 11
      freq 10
      pos 10642
      pos 10661
      pos 10723
      pos 10752
      pos 10755
      pos 10783
      pos 10805
      pos 10813
      pos 10864
      pos 10906
    doc 12
      freq 10
      pos 9492
      pos 9511
      pos 9573
      pos 9602
      pos 9605
      pos 9633
      pos 9655
      pos 9663
      pos 9714
      pos 9756
    doc 13
      freq 10
      pos 7107
      pos 7126
      pos 7188
      pos 7217
      pos 7220
      pos 7248
      pos 7270
      pos 7278
      pos 7329
      pos 7371
    doc 14
      freq 10
      pos 5573
      pos 5592
      pos 5654
      pos 5683
      pos 5686
      pos 5714
      pos 5736
      pos 5744
      pos 5795
      pos 5837
    doc 15
      freq 10
      pos 4092
      pos 4111
      pos 4173
      pos 4202
      pos 4205
      pos 4233
      pos 4255
      pos 4263
      pos 4314
      pos 4356
    doc 16
      freq 10
      pos 2703
      pos 2722
      pos 2784
      pos 2813
      pos 2816
      pos 2844
      pos 2866
      pos 2874
      pos 2925
      pos 2967
    doc 17
      freq 10
      pos 2427
      pos 2446
      pos 2508
      pos 2537
      pos 2540
      pos 2568
      pos 2590
      pos 2598
      pos 2649
      pos 2691
    doc 18
      freq 10
      pos 2215
      pos 2234
      pos 2296
      pos 2325
      pos 2328
      pos 2356
      pos 2378
      pos 2386
      pos 2437
      pos 2479
    skipList 
      level 0
        skipDoc 7
        skipDocFP 2000285
        impacts 
          impact 
            freq 10
            norm 100
          impact 
            freq 11
            norm 108
        impactsEnd 
        skipDoc 15
        skipDocFP 2001718
        impacts 
          impact 
            freq 10
            norm 95
        impactsEnd 
  term rigney
    doc 2
      freq 3
      pos 3017
      pos 3038
      pos 3090
  term rijhsinghan
    doc 2
      freq 1
      pos 2992
  term rijsinghan
    doc 2
      freq 2
      pos 2901
      pos 3599
  term ring
    doc 5
      freq 2
      pos 4403
      pos 4417
    doc 7
      freq 4
      pos 869
      pos 975
      pos 2279
      pos 2427
  term rio
    doc 1
      freq 1
      pos 9287
    doc 3
      freq 1
      pos 4756
  term rip
    doc 0
      freq 1
      pos 11663
    doc 7
      freq 1
      pos 2513
  term rirs
    doc 12
      freq 1
      pos 1487
  term risk
    doc 0
      freq 1
      pos 16654
    doc 18
      freq 1
      pos 478
  term risks
    doc 0
      freq 1
      pos 16706
    doc 18
      freq 3
      pos 372
      pos 465
      pos 499
  term riverston
    doc 3
      freq 1
      pos 4887
  term riverstonenet.com
    doc 3
      freq 1
      pos 4899
  term rjs
    doc 11
      freq 1
      pos 10533
  term rk10bj1szdvcckicpn6sdpuz80bg2bb40rex4nls9h
    doc 10
      freq 1
      pos 12665
  term rl47w
    doc 10
      freq 2
      pos 6897
      pos 6901
  term roach
    doc 10
      freq 1
      pos 12128
    doc 11
      freq 1
      pos 9489
    doc 13
      freq 1
      pos 6907
  term road
    doc 3
      freq 1
      pos 4952
    doc 6
      freq 1
      pos 3205
    doc 14
      freq 1
      pos 5531
  term roam
    doc 12
      freq 1
      pos 5626
  term rob
    doc 12
      freq 2
      pos 6780
      pos 6814
  term robert
    doc 4
      freq 1
      pos 5472
    doc 10
      freq 1
      pos 12113
    doc 11
      freq 1
      pos 10526
    doc 15
      freq 1
      pos 3851
  term robles
    doc 1
      freq 1
      pos 9288
    doc 3
      freq 1
      pos 4757
  term robust
    doc 12
      freq 1
      pos 3203
    doc 13
      freq 2
      pos 2087
      pos 2314
  term robustness
    doc 12
      freq 1
      pos 3274
    doc 13
      freq 1
      pos 2108
  term rock
    doc 13
      freq 1
      pos 3069
  term rod
    doc 13
      freq 1
      pos 7007
  term rod.walsh
    doc 13
      freq 1
      pos 7020
  term roese
    doc 2
      freq 1
      pos 3169
  term roger
    doc 2
      freq 2
      pos 1456
      pos 2277
  term rogers
    doc 6
      freq 1
      pos 3157
  term rogue
    doc 10
      freq 1
      pos 10090
    doc 17
      freq 2
      pos 1714
      pos 1727
  term rohan
    doc 10
      freq 1
      pos 12111
    doc 11
      freq 1
      pos 9479
  term role
    doc 2
      freq 2
      pos 3552
      pos 4735
    doc 10
      freq 14
      pos 1772
      pos 2103
      pos 2114
      pos 2133
      pos 2147
      pos 2166
      pos 2213
      pos 2323
      pos 3800
      pos 4580
      pos 5983
      pos 6024
      pos 6320
      pos 6959
    doc 11
      freq 1
      pos 7723
  term rollover
    doc 10
      freq 1
      pos 5681
  term rolls
    doc 9
      freq 1
      pos 1426
  term romascanu
    doc 2
      freq 5
      pos 2920
      pos 3190
      pos 3462
      pos 3766
      pos 4036
  term root
    doc 10
      freq 3
      pos 10871
      pos 11782
      pos 11793
    doc 12
      freq 3
      pos 7522
      pos 8030
      pos 8054
    doc 13
      freq 1
      pos 2246
    doc 14
      freq 1
      pos 2390
  term rose
    doc 12
      freq 1
      pos 6779
    doc 14
      freq 1
      pos 5439
    doc 18
      freq 4
      pos 2045
      pos 2070
      pos 2091
      pos 2114
  term rosen
    doc 1
      freq 5
      pos 11
      pos 8930
      pos 9074
      pos 9100
      pos 9559
    doc 3
      freq 4
      pos 11
      pos 4363
      pos 4386
      pos 5924
    doc 8
      freq 5
      pos 1788
      pos 1963
      pos 1987
      pos 2055
      pos 2079
  term rosenberg
    doc 2
      freq 1
      pos 6371
    doc 5
      freq 1
      pos 4316
    doc 10
      freq 5
      pos 12116
      pos 12140
      pos 13091
      pos 13152
      pos 13387
    doc 11
      freq 5
      pos 22
      pos 1464
      pos 9630
      pos 9656
      pos 10565
    doc 13
      freq 1
      pos 6829
  term roughly
    doc 12
      freq 1
      pos 2730
  term rounded
    doc 0
      freq 1
      pos 6803
  term roundtrip
    doc 5
      freq 2
      pos 2157
      pos 2234
  term routability
    doc 9
      freq 4
      pos 182
      pos 267
      pos 769
      pos 1234
  term route
    doc 0
      freq 4
      pos 557
      pos 4033
      pos 11684
      pos 16076
    doc 4
      freq 7
      pos 2170
      pos 2200
      pos 2334
      pos 2641
      pos 2648
      pos 5116
      pos 5704
    doc 7
      freq 2
      pos 762
      pos 2152
    doc 8
      freq 1
      pos 1505
    doc 9
      freq 3
      pos 20
      pos 167
      pos 1753
    doc 10
      freq 1
      pos 4562
    doc 11
      freq 8
      pos 1501
      pos 3794
      pos 5931
      pos 6377
      pos 7337
      pos 8902
      pos 8947
      pos 9261
  term routed
    doc 10
      freq 4
      pos 8788
      pos 8882
      pos 8931
      pos 10491
  term routeing
    doc 0
      freq 1
      pos 16893
  term router
    doc 0
      freq 16
      pos 480
      pos 547
      pos 579
      pos 2783
      pos 4434
      pos 4441
      pos 4471
      pos 4621
      pos 7127
      pos 7131
      pos 13305
      pos 15472
      pos 16004
      pos 16373
      pos 16580
      pos 16590
    doc 1
      freq 24
      pos 1125
      pos 1131
      pos 1721
      pos 2687
      pos 3186
      pos 3195
      pos 7355
      pos 7370
      pos 7403
      pos 7410
      pos 7427
      pos 7455
      pos 7528
      pos 7548
      pos 7551
      pos 7588
      pos 7592
      pos 7612
      pos 7624
      pos 7668
      pos 7677
      pos 7689
      pos 7696
      pos 7707
    doc 3
      freq 4
      pos 781
      pos 787
      pos 2870
      pos 4264
    doc 4
      freq 7
      pos 2012
      pos 2236
      pos 2515
      pos 2661
      pos 2866
      pos 3116
      pos 3129
    doc 7
      freq 1
      pos 2002
    doc 12
      freq 3
      pos 3909
      pos 4069
      pos 7731
    doc 15
      freq 2
      pos 743
      pos 785
  term router's
    doc 0
      freq 1
      pos 16289
    doc 4
      freq 1
      pos 2540
  term routers
    doc 0
      freq 4
      pos 738
      pos 4063
      pos 16070
      pos 16087
    doc 1
      freq 2
      pos 8030
      pos 8610
    doc 3
      freq 1
      pos 510
    doc 4
      freq 1
      pos 4480
    doc 7
      freq 1
      pos 2716
    doc 12
      freq 1
      pos 7584
  term routes
    doc 0
      freq 9
      pos 1357
      pos 1809
      pos 2787
      pos 3514
      pos 4068
      pos 4082
      pos 12852
      pos 16074
      pos 16403
  term routhier
    doc 0
      freq 1
      pos 17113
  term routing
    doc 0
      freq 13
      pos 125
      pos 133
      pos 317
      pos 331
      pos 1133
      pos 1146
      pos 2482
      pos 3397
      pos 10846
      pos 10850
      pos 11386
      pos 11390
      pos 16969
    doc 4
      freq 4
      pos 402
      pos 2297
      pos 2337
      pos 3162
    doc 7
      freq 12
      pos 900
      pos 906
      pos 991
      pos 1073
      pos 1420
      pos 1976
      pos 2364
      pos 2370
      pos 2446
      pos 2463
      pos 2479
      pos 2647
    doc 9
      freq 1
      pos 880
    doc 10
      freq 3
      pos 4566
      pos 10590
      pos 10677
    doc 11
      freq 1
      pos 7372
  term row
    doc 0
      freq 11
      pos 1594
      pos 3059
      pos 3299
      pos 3906
      pos 4418
      pos 4681
      pos 5295
      pos 5532
      pos 5702
      pos 10137
      pos 11436
  term row's
    doc 0
      freq 1
      pos 2238
  term rows
    doc 0
      freq 18
      pos 3075
      pos 3109
      pos 3157
      pos 3437
      pos 3608
      pos 4124
      pos 4500
      pos 5261
      pos 5457
      pos 5567
      pos 8872
      pos 9474
      pos 9657
      pos 9883
      pos 10021
      pos 10965
      pos 11754
      pos 12093
  term rowstatus
    doc 0
      freq 13
      pos 1013
      pos 3172
      pos 3233
      pos 3687
      pos 3882
      pos 4191
      pos 4382
      pos 5488
      pos 5647
      pos 10037
      pos 10107
      pos 11055
      pos 11404
  term roy
    doc 6
      freq 1
      pos 3145
    doc 12
      freq 2
      pos 7773
      pos 7790
  term rp0y1zos25ebot47nu8ksb8rd
    doc 10
      freq 1
      pos 12624
  term rp7vr1x
    doc 11
      freq 1
      pos 10431
  term rpc
    doc 7
      freq 2
      pos 2733
      pos 2747
  term rpjjmpwd7akcecqdgbtrznwv
    doc 10
      freq 1
      pos 6220
  term rport
    doc 11
      freq 1
      pos 3789
  term rpwn9d
    doc 11
      freq 1
      pos 10165
  term rq
    doc 11
      freq 1
      pos 9889
  term rqflq
    doc 10
      freq 1
      pos 6895
  term rr
    doc 12
      freq 4
      pos 7498
      pos 7830
      pos 7836
      pos 8412
    doc 14
      freq 8
      pos 304
      pos 1783
      pos 1808
      pos 1816
      pos 1855
      pos 2331
      pos 2401
      pos 5415
  term rr's
    doc 14
      freq 1
      pos 1827
  term rrs
    doc 12
      freq 2
      pos 294
      pos 2800
    doc 14
      freq 13
      pos 225
      pos 321
      pos 2134
      pos 2433
      pos 2510
      pos 2525
      pos 2529
      pos 2542
      pos 2577
      pos 2601
      pos 2676
      pos 2716
      pos 2774
    doc 18
      freq 2
      pos 827
      pos 1534
  term rrset
    doc 14
      freq 1
      pos 1820
    doc 18
      freq 2
      pos 1169
      pos 1201
  term rrsets
    doc 12
      freq 26
      pos 1173
      pos 1177
      pos 1187
      pos 1199
      pos 2814
      pos 8140
      pos 8156
      pos 8160
      pos 8250
      pos 8295
      pos 8312
      pos 8362
      pos 8404
      pos 8440
      pos 8561
      pos 8603
      pos 8781
      pos 8800
      pos 8815
      pos 8822
      pos 9022
      pos 9028
      pos 9105
      pos 9140
      pos 9309
      pos 9358
  term rrsig
    doc 18
      freq 8
      pos 803
      pos 968
      pos 1014
      pos 1021
      pos 1139
      pos 1458
      pos 1528
      pos 1645
  term rrsigs
    doc 18
      freq 1
      pos 1155
  term rs36ot
    doc 10
      freq 1
      pos 12720
  term rsa
    doc 5
      freq 3
      pos 832
      pos 4376
      pos 4389
    doc 10
      freq 16
      pos 5459
      pos 5484
      pos 5488
      pos 5540
      pos 6162
      pos 6205
      pos 6243
      pos 6549
      pos 6664
      pos 6829
      pos 6874
      pos 7252
      pos 7379
      pos 12037
      pos 12248
      pos 12265
  term rsvp
    doc 6
      freq 2
      pos 425
      pos 2884
  term rtcp
    doc 6
      freq 2
      pos 785
      pos 3056
  term rtfouayhnhfc3t
    doc 11
      freq 1
      pos 10065
  term rtkyhaadvukope6edyyj4550pq
    doc 11
      freq 1
      pos 10432
  term rtp
    doc 6
      freq 4
      pos 782
      pos 2836
      pos 3051
      pos 3072
    doc 10
      freq 3
      pos 6397
      pos 6534
      pos 6697
    doc 11
      freq 39
      pos 1552
      pos 1559
      pos 2270
      pos 2277
      pos 3188
      pos 3195
      pos 3421
      pos 3428
      pos 4064
      pos 4071
      pos 4329
      pos 4336
      pos 4510
      pos 4517
      pos 4724
      pos 4731
      pos 5215
      pos 5222
      pos 5372
      pos 5379
      pos 5520
      pos 5527
      pos 5680
      pos 5687
      pos 6000
      pos 6007
      pos 6224
      pos 6231
      pos 6910
      pos 6917
      pos 7248
      pos 7255
      pos 8204
      pos 8211
      pos 8533
      pos 8540
      pos 9128
      pos 9135
      pos 9305
  term rtpmap
    doc 10
      freq 3
      pos 6401
      pos 6538
      pos 6701
    doc 11
      freq 19
      pos 1563
      pos 2281
      pos 3199
      pos 3432
      pos 4075
      pos 4340
      pos 4521
      pos 4735
      pos 5226
      pos 5383
      pos 5531
      pos 5691
      pos 6011
      pos 6235
      pos 6921
      pos 7259
      pos 8215
      pos 8544
      pos 9139
  term rubens
    doc 2
      freq 2
      pos 3021
      pos 3070
  term rudimentary
    doc 13
      freq 1
      pos 432
  term rue
    doc 17
      freq 1
      pos 2387
  term rufus.example.org
    doc 16
      freq 2
      pos 1959
      pos 2327
  term rule
    doc 4
      freq 4
      pos 1676
      pos 4399
      pos 5651
      pos 5679
    doc 11
      freq 2
      pos 1713
      pos 1788
  term rules
    doc 0
      freq 1
      pos 10350
    doc 1
      freq 3
      pos 2797
      pos 3350
      pos 3597
    doc 4
      freq 7
      pos 179
      pos 381
      pos 1199
      pos 1346
      pos 1352
      pos 2917
      pos 5738
    doc 7
      freq 2
      pos 925
      pos 2389
    doc 10
      freq 1
      pos 5100
    doc 11
      freq 1
      pos 8425
    doc 13
      freq 1
      pos 4442
    doc 15
      freq 1
      pos 925
    doc 16
      freq 1
      pos 845
    doc 17
      freq 5
      pos 200
      pos 308
      pos 331
      pos 345
      pos 692
    skipList 
      level 0
        skipDoc 15
        skipDocFP 2016397
        impacts 
          impact 
            freq 2
            norm 100
          impact 
            freq 7
            norm 108
        impactsEnd 
  term rumafkddqco7hb
    doc 11
      freq 1
      pos 10131
  term run
    doc 0
      freq 3
      pos 5097
      pos 5131
      pos 6203
    doc 2
      freq 1
      pos 1318
    doc 5
      freq 1
      pos 3544
    doc 12
      freq 1
      pos 6627
    doc 15
      freq 6
      pos 1212
      pos 1780
      pos 1809
      pos 1832
      pos 1844
      pos 2745
  term running
    doc 0
      freq 5
      pos 477
      pos 544
      pos 2348
      pos 5924
      pos 13612
    doc 3
      freq 1
      pos 2913
    doc 10
      freq 1
      pos 11285
    doc 12
      freq 1
      pos 4393
    doc 13
      freq 1
      pos 6471
    doc 15
      freq 2
      pos 894
      pos 1491
  term runs
    doc 0
      freq 1
      pos 4991
  term runt
    doc 3
      freq 1
      pos 3113
  term rup
    doc 11
      freq 1
      pos 10269
  term russ
    doc 5
      freq 1
      pos 4092
  term rvbbrz2xmwewy3lcs8rhbuthmk
    doc 11
      freq 1
      pos 10055
  term rwfc6snybjhpofimvrj2okeeoq6qbb58aqspcm86u350uqoeghrulys
    doc 10
      freq 1
      pos 12604
  term ry
    doc 11
      freq 1
      pos 10074
  term rz.tu
    doc 15
      freq 1
      pos 4061
  term rzgnz
    doc 11
      freq 1
      pos 10108
  term s
    doc 0
      freq 2
      pos 16943
      pos 17114
    doc 1
      freq 3
      pos 1545
      pos 8896
      pos 9149
    doc 2
      freq 6
      pos 611
      pos 668
      pos 693
      pos 2250
      pos 2252
      pos 3020
    doc 3
      freq 3
      pos 4312
      pos 4494
      pos 4516
    doc 4
      freq 13
      pos 12
      pos 2034
      pos 5178
      pos 5231
      pos 5269
      pos 5289
      pos 5306
      pos 5333
      pos 5350
      pos 5368
      pos 5385
      pos 5411
      pos 5424
    doc 5
      freq 4
      pos 3
      pos 2427
      pos 2429
      pos 4124
    doc 6
      freq 15
      pos 400
      pos 494
      pos 1238
      pos 1250
      pos 1393
      pos 1444
      pos 1519
      pos 2197
      pos 2316
      pos 2875
      pos 2877
      pos 2879
      pos 2935
      pos 2972
      pos 3066
    doc 7
      freq 1
      pos 1805
    doc 8
      freq 2
      pos 1764
      pos 2101
    doc 9
      freq 3
      pos 1667
      pos 1691
      pos 1705
    doc 10
      freq 13
      pos 535
      pos 561
      pos 2406
      pos 2429
      pos 6383
      pos 6508
      pos 6683
      pos 8839
      pos 12411
      pos 12412
      pos 12413
      pos 13118
      pos 13214
    doc 11
      freq 28
      pos 1489
      pos 1541
      pos 2259
      pos 3177
      pos 3410
      pos 3754
      pos 4053
      pos 4318
      pos 4499
      pos 4713
      pos 5204
      pos 5361
      pos 5509
      pos 5669
      pos 5989
      pos 6213
      pos 7237
      pos 8193
      pos 8522
      pos 9117
      pos 9294
      pos 9518
      pos 9816
      pos 9817
      pos 9818
      pos 9909
      pos 9942
      pos 9967
    doc 12
      freq 9
      pos 2957
      pos 3105
      pos 7015
      pos 7055
      pos 7074
      pos 7261
      pos 7427
      pos 7774
      pos 7791
    doc 13
      freq 14
      pos 994
      pos 998
      pos 1415
      pos 1419
      pos 1433
      pos 1435
      pos 1452
      pos 1520
      pos 3848
      pos 5000
      pos 5356
      pos 5370
      pos 6625
      pos 6737
    doc 14
      freq 18
      pos 596
      pos 611
      pos 909
      pos 1287
      pos 1345
      pos 1565
      pos 4156
      pos 4193
      pos 4260
      pos 4385
      pos 4477
      pos 4558
      pos 4870
      pos 5139
      pos 5157
      pos 5271
      pos 5438
      pos 5470
    doc 15
      freq 2
      pos 14
      pos 3911
    doc 16
      freq 17
      pos 1703
      pos 1790
      pos 1818
      pos 1835
      pos 1844
      pos 1943
      pos 2079
      pos 2088
      pos 2103
      pos 2171
      pos 2199
      pos 2240
      pos 2311
      pos 2407
      pos 2426
      pos 2443
      pos 2452
    doc 17
      freq 3
      pos 2029
      pos 2075
      pos 2368
    doc 18
      freq 5
      pos 3
      pos 2069
      pos 2090
      pos 2113
      pos 2128
    skipList 
      level 0
        skipDoc 7
        skipDocFP 2018428
        impacts 
          impact 
            freq 1
            norm 100
          impact 
            freq 15
            norm 101
        impactsEnd 
        skipDoc 15
        skipDocFP 2019311
        impacts 
          impact 
            freq 3
            norm 95
          impact 
            freq 18
            norm 107
          impact 
            freq 28
            norm 114
        impactsEnd 
  term s2005
    doc 12
      freq 2
      pos 4683
      pos 7811
  term s2005b
    doc 12
      freq 2
      pos 4686
      pos 7825
  term s2005c
    doc 12
      freq 2
      pos 5257
      pos 7843
  term s32j
    doc 10
      freq 1
      pos 12560
  term s5pq0n5sxpk
    doc 10
      freq 1
      pos 12762
  term s7dwg8vv
    doc 11
      freq 1
      pos 10274
  term s8mxbgb9r8k38f
    doc 10
      freq 1
      pos 12638
  term s8nr
    doc 10
      freq 1
      pos 12600
  term sa
    doc 4
      freq 2
      pos 4119
      pos 5366
  term sadot
    doc 2
      freq 1
      pos 3311
  term safe
    doc 10
      freq 1
      pos 9689
    doc 12
      freq 1
      pos 3840
  term safely
    doc 12
      freq 1
      pos 8459
  term safety
    doc 9
      freq 1
      pos 1063
  term sai
    doc 1
      freq 5
      pos 3510
      pos 3544
      pos 3552
      pos 3577
      pos 4770
  term said
    doc 10
      freq 3
      pos 2685
      pos 2716
      pos 11144
    doc 18
      freq 1
      pos 227
  term saii
    doc 1
      freq 16
      pos 3494
      pos 3518
      pos 3539
      pos 3692
      pos 3749
      pos 3823
      pos 3856
      pos 3874
      pos 3893
      pos 3918
      pos 4314
      pos 4409
      pos 4616
      pos 4790
      pos 5537
      pos 7213
  term sall
    doc 1
      freq 1
      pos 9342
    doc 3
      freq 1
      pos 4845
  term saluj
    doc 0
      freq 1
      pos 17152
  term sam
    doc 14
      freq 1
      pos 5343
  term same
    doc 0
      freq 11
      pos 2209
      pos 4844
      pos 5979
      pos 6006
      pos 6031
      pos 6058
      pos 7070
      pos 10098
      pos 11271
      pos 12026
      pos 13396
    doc 1
      freq 15
      pos 1681
      pos 2407
      pos 2759
      pos 2885
      pos 3438
      pos 4573
      pos 4598
      pos 4606
      pos 6792
      pos 6981
      pos 7421
      pos 7476
      pos 7480
      pos 8602
      pos 9461
    doc 2
      freq 2
      pos 3799
      pos 6120
    doc 3
      freq 8
      pos 2397
      pos 2860
      pos 2934
      pos 3443
      pos 5059
      pos 5120
      pos 5154
      pos 5615
    doc 4
      freq 4
      pos 862
      pos 1134
      pos 2532
      pos 3884
    doc 5
      freq 3
      pos 3152
      pos 3349
      pos 3520
    doc 6
      freq 1
      pos 695
    doc 9
      freq 4
      pos 407
      pos 786
      pos 1216
      pos 1230
    doc 10
      freq 12
      pos 1283
      pos 2070
      pos 2832
      pos 3968
      pos 3976
      pos 6743
      pos 6750
      pos 7855
      pos 8293
      pos 8569
      pos 8947
      pos 9706
    doc 11
      freq 8
      pos 946
      pos 1057
      pos 1270
      pos 1640
      pos 2477
      pos 4583
      pos 8712
      pos 8803
    doc 12
      freq 9
      pos 267
      pos 2289
      pos 2438
      pos 2494
      pos 2817
      pos 5483
      pos 5508
      pos 6203
      pos 6319
    doc 13
      freq 9
      pos 3737
      pos 4517
      pos 4526
      pos 5149
      pos 5172
      pos 5295
      pos 5520
      pos 5572
      pos 6249
    doc 14
      freq 2
      pos 701
      pos 1077
    doc 15
      freq 10
      pos 897
      pos 1120
      pos 1847
      pos 1932
      pos 1959
      pos 1987
      pos 2109
      pos 2136
      pos 2960
      pos 3474
    doc 17
      freq 7
      pos 1527
      pos 1533
      pos 1537
      pos 1541
      pos 1718
      pos 1739
      pos 1784
    doc 18
      freq 2
      pos 928
      pos 1116
    skipList 
      level 0
        skipDoc 9
        skipDocFP 2023264
        impacts 
          impact 
            freq 4
            norm 95
          impact 
            freq 8
            norm 107
          impact 
            freq 15
            norm 113
        impactsEnd 
        skipDoc 18
        skipDocFP 2024170
        impacts 
          impact 
            freq 2
            norm 97
          impact 
            freq 7
            norm 98
          impact 
            freq 10
            norm 104
          impact 
            freq 12
            norm 116
        impactsEnd 
  term sampl
    doc 6
      freq 3
      pos 1267
      pos 1421
      pos 1456
  term samples
    doc 6
      freq 1
      pos 1907
  term sampling
    doc 6
      freq 1
      pos 1119
  term samuel
    doc 18
      freq 2
      pos 2159
      pos 2164
  term san
    doc 1
      freq 4
      pos 9210
      pos 9243
      pos 9290
      pos 9304
    doc 3
      freq 1
      pos 4759
    doc 4
      freq 1
      pos 6067
    doc 10
      freq 1
      pos 13441
    doc 16
      freq 1
      pos 2658
  term sandford
    doc 14
      freq 1
      pos 5510
  term sandy
    doc 14
      freq 1
      pos 5512
  term santa
    doc 3
      freq 1
      pos 4893
  term sap
    doc 13
      freq 5
      pos 449
      pos 1176
      pos 1587
      pos 1637
      pos 1756
  term sasson
    doc 8
      freq 1
      pos 2013
  term sat
    doc 11
      freq 1
      pos 3840
  term satellit
    doc 13
      freq 1
      pos 544
  term satisfy
    doc 9
      freq 1
      pos 1117
    doc 13
      freq 1
      pos 1038
  term satish
    doc 0
      freq 1
      pos 15919
  term satop
    doc 1
      freq 6
      pos 561
      pos 650
      pos 701
      pos 2377
      pos 8996
      pos 9009
    doc 8
      freq 6
      pos 741
      pos 749
      pos 756
      pos 764
      pos 1886
      pos 1899
  term saturn.example.com
    doc 11
      freq 4
      pos 8733
      pos 8751
      pos 8823
      pos 8841
  term saval
    doc 7
      freq 1
      pos 1787
  term save
    doc 13
      freq 3
      pos 3443
      pos 4096
      pos 4488
  term saved
    doc 0
      freq 1
      pos 5853
  term savol
    doc 4
      freq 1
      pos 5499
    doc 12
      freq 4
      pos 16
      pos 7354
      pos 7532
      pos 9455
  term saw
    doc 0
      freq 2
      pos 7856
      pos 13109
  term say
    doc 6
      freq 1
      pos 2538
    doc 10
      freq 1
      pos 10487
    doc 15
      freq 1
      pos 1599
  term says
    doc 1
      freq 1
      pos 6672
  term saz0pd
    doc 11
      freq 1
      pos 10490
  term sbc
    doc 6
      freq 1
      pos 3142
  term sbdiboakscm
    doc 11
      freq 1
      pos 10015
  term scalability
    doc 12
      freq 1
      pos 1497
    doc 13
      freq 11
      pos 266
      pos 1733
      pos 2679
      pos 3933
      pos 3945
      pos 3973
      pos 4312
      pos 4612
      pos 4654
      pos 4697
      pos 4880
  term scalabl
    doc 6
      freq 2
      pos 799
      pos 896
    doc 13
      freq 6
      pos 114
      pos 1655
      pos 3926
      pos 3982
      pos 4053
      pos 4633
  term scalar
    doc 0
      freq 1
      pos 610
    doc 11
      freq 7
      pos 268
      pos 276
      pos 4740
      pos 4749
      pos 4858
      pos 4948
      pos 4957
  term scalar02
    doc 11
      freq 1
      pos 4900
  term scalar02.23o0pd9vanlq3wnrlnewofjas9ui32
    doc 11
      freq 1
      pos 4926
  term scalarlg
    doc 11
      freq 1
      pos 5019
  term scalarlg.noase0of0234hn2qofoaf0232aewf2394r
    doc 11
      freq 1
      pos 5050
  term scale
    doc 4
      freq 1
      pos 867
    doc 6
      freq 1
      pos 418
    doc 13
      freq 2
      pos 1333
      pos 6675
  term scales
    doc 5
      freq 1
      pos 113
  term scenar
    doc 4
      freq 2
      pos 4671
      pos 4733
    doc 5
      freq 1
      pos 693
    doc 9
      freq 1
      pos 613
    doc 12
      freq 2
      pos 3063
      pos 3153
    doc 13
      freq 2
      pos 3901
      pos 6714
    doc 17
      freq 1
      pos 1764
  term scenarios
    doc 5
      freq 8
      pos 100
      pos 169
      pos 366
      pos 464
      pos 480
      pos 515
      pos 2513
      pos 2780
    doc 9
      freq 2
      pos 322
      pos 390
    doc 12
      freq 6
      pos 473
      pos 3968
      pos 4047
      pos 8118
      pos 8136
      pos 9252
    doc 13
      freq 5
      pos 727
      pos 1066
      pos 1088
      pos 1106
      pos 3705
    doc 15
      freq 2
      pos 208
      pos 561
  term schaad
    doc 10
      freq 1
      pos 12135
  term schedul
    doc 13
      freq 2
      pos 3416
      pos 3435
    doc 16
      freq 1
      pos 2051
  term scheduled
    doc 13
      freq 1
      pos 3324
  term schedules
    doc 13
      freq 3
      pos 403
      pos 627
      pos 630
  term scheduling
    doc 13
      freq 5
      pos 1624
      pos 2889
      pos 3014
      pos 3091
      pos 5701
  term schem
    doc 7
      freq 1
      pos 2026
    doc 10
      freq 8
      pos 261
      pos 2443
      pos 2598
      pos 4046
      pos 7396
      pos 7463
      pos 8446
      pos 11678
    doc 11
      freq 14
      pos 411
      pos 420
      pos 444
      pos 7281
      pos 7288
      pos 7317
      pos 7416
      pos 7427
      pos 7457
      pos 7478
      pos 7489
      pos 7895
      pos 7907
      pos 7999
    doc 13
      freq 1
      pos 1993
    doc 16
      freq 4
      pos 266
      pos 895
      pos 1277
      pos 2540
  term schemes
    doc 2
      freq 1
      pos 4707
    doc 5
      freq 1
      pos 851
    doc 10
      freq 1
      pos 542
    doc 11
      freq 4
      pos 425
      pos 5439
      pos 7557
      pos 7565
    doc 13
      freq 2
      pos 2347
      pos 4290
  term schiller
    doc 9
      freq 1
      pos 1688
  term schlyter
    doc 14
      freq 1
      pos 5495
    doc 18
      freq 1
      pos 2028
  term schoenwaelder
    doc 0
      freq 5
      pos 15965
      pos 17046
      pos 17067
      pos 17085
      pos 17117
  term school
    doc 15
      freq 1
      pos 4021
  term schooler
    doc 5
      freq 1
      pos 4332
    doc 10
      freq 1
      pos 13107
    doc 11
      freq 1
      pos 9646
    doc 13
      freq 1
      pos 6845
  term schulzrinn
    doc 5
      freq 1
      pos 4318
    doc 6
      freq 1
      pos 3063
    doc 10
      freq 4
      pos 13093
      pos 13156
      pos 13313
      pos 13391
    doc 11
      freq 4
      pos 26
      pos 9632
      pos 9660
      pos 10586
    doc 13
      freq 5
      pos 26
      pos 6831
      pos 6866
      pos 7058
      pos 7074
  term scienc
    doc 0
      freq 2
      pos 1110
      pos 17202
    doc 2
      freq 1
      pos 2864
    doc 11
      freq 2
      pos 10592
      pos 10595
    doc 13
      freq 1
      pos 7062
    doc 15
      freq 1
      pos 4026
  term sco
    doc 11
      freq 1
      pos 9898
  term scope
    doc 0
      freq 1
      pos 17343
    doc 1
      freq 4
      pos 956
      pos 2046
      pos 3318
      pos 9724
    doc 2
      freq 1
      pos 6521
    doc 3
      freq 10
      pos 716
      pos 1078
      pos 1497
      pos 1538
      pos 3137
      pos 4141
      pos 4170
      pos 5576
      pos 5863
      pos 6073
    doc 4
      freq 12
      pos 1880
      pos 2181
      pos 2376
      pos 2395
      pos 2404
      pos 2422
      pos 2437
      pos 4639
      pos 5087
      pos 5692
      pos 5935
      pos 6228
    doc 5
      freq 2
      pos 941
      pos 4558
    doc 6
      freq 2
      pos 2811
      pos 3358
    doc 7
      freq 1
      pos 3063
    doc 8
      freq 1
      pos 2280
    doc 9
      freq 1
      pos 1925
    doc 10
      freq 8
      pos 1573
      pos 3670
      pos 3851
      pos 9781
      pos 9868
      pos 10169
      pos 11418
      pos 13586
    doc 11
      freq 2
      pos 2050
      pos 10747
    doc 12
      freq 4
      pos 194
      pos 1254
      pos 4330
      pos 9597
    doc 13
      freq 6
      pos 144
      pos 1024
      pos 1486
      pos 2772
      pos 3349
      pos 7212
    doc 14
      freq 1
      pos 5678
    doc 15
      freq 2
      pos 1685
      pos 4197
    doc 16
      freq 3
      pos 413
      pos 1032
      pos 2808
    doc 17
      freq 2
      pos 1262
      pos 2532
    doc 18
      freq 1
      pos 2320
    skipList 
      level 0
        skipDoc 7
        skipDocFP 2032208
        impacts 
          impact 
            freq 1
            norm 100
          impact 
            freq 2
            norm 101
          impact 
            freq 10
            norm 107
          impact 
            freq 12
            norm 108
        impactsEnd 
        skipDoc 15
        skipDocFP 2032887
        impacts 
          impact 
            freq 1
            norm 95
          impact 
            freq 2
            norm 104
          impact 
            freq 6
            norm 109
          impact 
            freq 8
            norm 116
        impactsEnd 
  term scott
    doc 4
      freq 1
      pos 5484
    doc 11
      freq 1
      pos 9582
    doc 12
      freq 1
      pos 6778
    doc 18
      freq 1
      pos 2044
  term screen
    doc 6
      freq 1
      pos 2656
  term script
    doc 10
      freq 1
      pos 12365
    doc 11
      freq 1
      pos 9782
  term scripts
    doc 15
      freq 1
      pos 1906
  term sctp
    doc 11
      freq 1
      pos 3649
  term sd
    doc 13
      freq 2
      pos 457
      pos 6792
  term sdh
    doc 1
      freq 7
      pos 596
      pos 600
      pos 624
      pos 678
      pos 699
      pos 8986
      pos 9121
    doc 8
      freq 3
      pos 666
      pos 729
      pos 1876
  term sdlc
    doc 7
      freq 1
      pos 1064
  term sdp
    doc 5
      freq 5
      pos 2694
      pos 2699
      pos 2904
      pos 2906
      pos 4307
    doc 10
      freq 8
      pos 6369
      pos 6385
      pos 6510
      pos 6669
      pos 6685
      pos 9093
      pos 9153
      pos 9181
    doc 11
      freq 31
      pos 603
      pos 1500
      pos 2232
      pos 3165
      pos 3397
      pos 3535
      pos 3634
      pos 4039
      pos 4308
      pos 4486
      pos 4700
      pos 5191
      pos 5348
      pos 5496
      pos 5656
      pos 5816
      pos 5976
      pos 6200
      pos 6468
      pos 6631
      pos 6891
      pos 7125
      pos 7225
      pos 8174
      pos 8508
      pos 8995
      pos 9002
      pos 9060
      pos 9107
      pos 9284
      pos 9669
    doc 13
      freq 10
      pos 428
      pos 605
      pos 1179
      pos 1592
      pos 1599
      pos 1897
      pos 1927
      pos 5446
      pos 5588
      pos 6763
  term sdp01
    doc 11
      freq 2
      pos 9063
      pos 9086
  term sdpng
    doc 13
      freq 4
      pos 606
      pos 1961
      pos 1980
      pos 5590
  term sdr
    doc 13
      freq 2
      pos 460
      pos 6802
  term sdu
    doc 8
      freq 1
      pos 640
  term seachang
    doc 6
      freq 1
      pos 3121
  term seaman
    doc 2
      freq 1
      pos 3601
  term seamoby
    doc 2
      freq 1
      pos 6240
  term search
    doc 12
      freq 1
      pos 2428
    doc 13
      freq 1
      pos 2824
    doc 15
      freq 6
      pos 236
      pos 649
      pos 1338
      pos 1343
      pos 1407
      pos 2082
  term sec
    doc 4
      freq 2
      pos 4070
      pos 5421
    doc 11
      freq 3
      pos 3767
      pos 9523
      pos 9696
  term second
    doc 0
      freq 12
      pos 9343
      pos 12894
      pos 13148
      pos 13250
      pos 13467
      pos 13565
      pos 13657
      pos 13759
      pos 13832
      pos 13904
      pos 14044
      pos 14173
    doc 1
      freq 2
      pos 1525
      pos 8301
    doc 2
      freq 1
      pos 5776
    doc 4
      freq 1
      pos 1911
    doc 5
      freq 1
      pos 1694
    doc 6
      freq 3
      pos 1451
      pos 1850
      pos 1932
    doc 10
      freq 3
      pos 5358
      pos 8440
      pos 10529
    doc 11
      freq 2
      pos 972
      pos 3706
    doc 12
      freq 4
      pos 631
      pos 3755
      pos 4742
      pos 6404
    doc 15
      freq 1
      pos 1806
    doc 18
      freq 3
      pos 1001
      pos 1545
      pos 1685
    skipList 
      level 0
        skipDoc 11
        skipDocFP 2036702
        impacts 
          impact 
            freq 3
            norm 101
          impact 
            freq 12
            norm 120
        impactsEnd 
  term secondary
    doc 12
      freq 1
      pos 7063
  term secondly
    doc 10
      freq 1
      pos 10463
  term secondparam
    doc 11
      freq 1
      pos 1529
  term seconds
    doc 0
      freq 27
      pos 2545
      pos 2556
      pos 2587
      pos 2614
      pos 2625
      pos 2666
      pos 2676
      pos 2809
      pos 2834
      pos 4813
      pos 4836
      pos 5023
      pos 5082
      pos 5085
      pos 5123
      pos 6153
      pos 6802
      pos 7022
      pos 7033
      pos 7100
      pos 7112
      pos 7157
      pos 7168
      pos 9251
      pos 9263
      pos 11923
      pos 11935
    doc 10
      freq 2
      pos 8520
      pos 8560
    doc 12
      freq 5
      pos 2948
      pos 3003
      pos 3096
      pos 3116
      pos 3548
  term secret
    doc 9
      freq 1
      pos 252
    doc 10
      freq 3
      pos 583
      pos 892
      pos 994
    doc 12
      freq 1
      pos 6913
  term secretariat
    doc 0
      freq 1
      pos 17430
    doc 1
      freq 1
      pos 9811
    doc 2
      freq 2
      pos 652
      pos 6608
    doc 3
      freq 1
      pos 6160
    doc 4
      freq 1
      pos 6315
    doc 5
      freq 1
      pos 4645
    doc 6
      freq 1
      pos 3445
    doc 7
      freq 1
      pos 3150
    doc 8
      freq 1
      pos 2367
    doc 9
      freq 1
      pos 2012
    doc 10
      freq 1
      pos 13673
    doc 11
      freq 1
      pos 10834
    doc 12
      freq 1
      pos 9684
    doc 13
      freq 1
      pos 7299
    doc 14
      freq 1
      pos 5765
    doc 15
      freq 1
      pos 4284
    doc 16
      freq 1
      pos 2895
    doc 17
      freq 1
      pos 2619
    doc 18
      freq 1
      pos 2407
    skipList 
      level 0
        skipDoc 7
        skipDocFP 2038637
        impacts 
          impact 
            freq 1
            norm 100
          impact 
            freq 2
            norm 108
        impactsEnd 
        skipDoc 15
        skipDocFP 2038956
        impacts 
          impact 
            freq 1
            norm 95
        impactsEnd 
  term secretary
    doc 2
      freq 1
      pos 592
  term secrets
    doc 10
      freq 1
      pos 10115
  term section
    doc 0
      freq 12
      pos 216
      pos 417
      pos 1571
      pos 1687
      pos 1736
      pos 1787
      pos 1819
      pos 1841
      pos 1870
      pos 1982
      pos 2011
      pos 16733
    doc 1
      freq 12
      pos 2251
      pos 2291
      pos 2326
      pos 2349
      pos 2571
      pos 3138
      pos 4064
      pos 4867
      pos 5005
      pos 7736
      pos 8419
      pos 8631
    doc 2
      freq 1
      pos 708
    doc 3
      freq 5
      pos 1683
      pos 2155
      pos 3270
      pos 3469
      pos 5429
    doc 4
      freq 33
      pos 387
      pos 767
      pos 774
      pos 780
      pos 786
      pos 809
      pos 815
      pos 879
      pos 957
      pos 1295
      pos 1412
      pos 1683
      pos 1703
      pos 1711
      pos 2750
      pos 2996
      pos 3191
      pos 3232
      pos 3535
      pos 4376
      pos 4403
      pos 5565
      pos 5718
      pos 5731
      pos 5747
      pos 5767
      pos 5774
      pos 5778
      pos 5827
      pos 5867
      pos 5917
      pos 5991
      pos 5999
    doc 5
      freq 16
      pos 1106
      pos 1163
      pos 1203
      pos 1489
      pos 1514
      pos 1519
      pos 1634
      pos 1679
      pos 2003
      pos 2064
      pos 2255
      pos 3727
      pos 3760
      pos 3950
      pos 3973
      pos 4153
    doc 6
      freq 1
      pos 649
    doc 8
      freq 1
      pos 1737
    doc 9
      freq 3
      pos 529
      pos 1084
      pos 1618
    doc 10
      freq 34
      pos 1352
      pos 1778
      pos 2260
      pos 2418
      pos 2461
      pos 2625
      pos 3138
      pos 3296
      pos 3365
      pos 3498
      pos 4161
      pos 4214
      pos 4262
      pos 4398
      pos 4499
      pos 5303
      pos 5472
      pos 5564
      pos 5948
      pos 6122
      pos 6148
      pos 6159
      pos 8310
      pos 8316
      pos 8488
      pos 9230
      pos 9747
      pos 10762
      pos 11498
      pos 11567
      pos 11655
      pos 11749
      pos 11862
      pos 12210
    doc 11
      freq 7
      pos 830
      pos 3255
      pos 4181
      pos 4205
      pos 7006
      pos 7153
      pos 9759
    doc 12
      freq 32
      pos 582
      pos 632
      pos 647
      pos 668
      pos 680
      pos 711
      pos 902
      pos 971
      pos 1429
      pos 1900
      pos 2141
      pos 2144
      pos 2467
      pos 2933
      pos 3169
      pos 3503
      pos 4144
      pos 5806
      pos 6088
      pos 6137
      pos 6350
      pos 6496
      pos 6749
      pos 6751
      pos 7630
      pos 8111
      pos 8227
      pos 8304
      pos 8385
      pos 8667
      pos 8771
      pos 9039
    doc 13
      freq 3
      pos 3870
      pos 5648
      pos 5777
    doc 14
      freq 10
      pos 378
      pos 672
      pos 1839
      pos 1860
      pos 1881
      pos 1905
      pos 1952
      pos 2180
      pos 2288
      pos 2948
    doc 15
      freq 2
      pos 819
      pos 2565
    doc 16
      freq 11
      pos 1210
      pos 1786
      pos 1805
      pos 1814
      pos 2066
      pos 2075
      pos 2167
      pos 2186
      pos 2195
      pos 2422
      pos 2461
    doc 18
      freq 11
      pos 378
      pos 457
      pos 505
      pos 676
      pos 683
      pos 821
      pos 1176
      pos 1206
      pos 1249
      pos 1585
      pos 1900
    skipList 
      level 0
        skipDoc 8
        skipDocFP 2039873
        impacts 
          impact 
            freq 1
            norm 97
          impact 
            freq 16
            norm 104
          impact 
            freq 33
            norm 108
        impactsEnd 
        skipDoc 16
        skipDocFP 2041264
        impacts 
          impact 
            freq 3
            norm 95
          impact 
            freq 11
            norm 99
          impact 
            freq 32
            norm 113
          impact 
            freq 34
            norm 116
        impactsEnd 
  term sections
    doc 1
      freq 1
      pos 2082
    doc 4
      freq 3
      pos 979
      pos 2059
      pos 6004
    doc 10
      freq 1
      pos 12146
    doc 11
      freq 2
      pos 627
      pos 9510
    doc 12
      freq 2
      pos 699
      pos 951
    doc 13
      freq 1
      pos 2754
  term secur
    doc 0
      freq 3
      pos 16147
      pos 16763
      pos 16780
    doc 1
      freq 1
      pos 8397
    doc 2
      freq 1
      pos 6071
    doc 5
      freq 6
      pos 156
      pos 211
      pos 2870
      pos 4228
      pos 4267
      pos 4366
    doc 9
      freq 1
      pos 1593
    doc 10
      freq 2
      pos 2385
      pos 8250
    doc 12
      freq 4
      pos 4616
      pos 6051
      pos 6279
      pos 7112
    doc 17
      freq 1
      pos 1555
    skipList 
      level 0
        skipDoc 17
        skipDocFP 2044084
        impacts 
          impact 
            freq 1
            norm 95
          impact 
            freq 6
            norm 104
        impactsEnd 
  term secured
    doc 3
      freq 1
      pos 4120
    doc 5
      freq 3
      pos 990
      pos 1034
      pos 3034
    doc 10
      freq 1
      pos 10034
    doc 13
      freq 1
      pos 5755
    doc 14
      freq 1
      pos 116
  term securely
    doc 10
      freq 1
      pos 127
  term securing
    doc 4
      freq 1
      pos 4521
    doc 9
      freq 1
      pos 17
    doc 10
      freq 5
      pos 285
      pos 4404
      pos 9041
      pos 9061
      pos 10009
  term security
    doc 0
      freq 7
      pos 169
      pos 15977
      pos 16653
      pos 16688
      pos 16723
      pos 16756
      pos 16820
    doc 1
      freq 17
      pos 383
      pos 389
      pos 394
      pos 7928
      pos 7977
      pos 7991
      pos 7996
      pos 8019
      pos 8022
      pos 8046
      pos 8208
      pos 8213
      pos 8382
      pos 8405
      pos 8407
      pos 8645
      pos 8829
    doc 2
      freq 15
      pos 155
      pos 1433
      pos 1941
      pos 1957
      pos 2014
      pos 2127
      pos 2152
      pos 2179
      pos 2688
      pos 2854
      pos 5125
      pos 5638
      pos 5737
      pos 5853
      pos 5904
    doc 3
      freq 8
      pos 267
      pos 543
      pos 4066
      pos 4079
      pos 4098
      pos 4110
      pos 4129
      pos 4146
    doc 4
      freq 17
      pos 223
      pos 2686
      pos 4020
      pos 4046
      pos 4065
      pos 4116
      pos 4227
      pos 4253
      pos 4276
      pos 4291
      pos 4305
      pos 5372
      pos 5414
      pos 5428
      pos 5825
      pos 5834
      pos 5958
    doc 5
      freq 31
      pos 275
      pos 299
      pos 396
      pos 523
      pos 526
      pos 884
      pos 923
      pos 932
      pos 945
      pos 957
      pos 1540
      pos 1545
      pos 1558
      pos 1566
      pos 1646
      pos 1691
      pos 1734
      pos 1760
      pos 1780
      pos 2741
      pos 2744
      pos 2783
      pos 2823
      pos 2982
      pos 3142
      pos 3159
      pos 3167
      pos 3600
      pos 3722
      pos 3845
      pos 4279
    doc 6
      freq 3
      pos 131
      pos 2767
      pos 2780
    doc 7
      freq 8
      pos 145
      pos 1113
      pos 1166
      pos 1731
      pos 1736
      pos 2310
      pos 2759
      pos 2772
    doc 8
      freq 3
      pos 165
      pos 1677
      pos 1707
    doc 9
      freq 8
      pos 133
      pos 159
      pos 1009
      pos 1108
      pos 1133
      pos 1599
      pos 1696
      pos 1755
    doc 10
      freq 19
      pos 93
      pos 268
      pos 517
      pos 532
      pos 541
      pos 1627
      pos 3286
      pos 5290
      pos 8130
      pos 8206
      pos 8287
      pos 8320
      pos 9139
      pos 9208
      pos 10354
      pos 10985
      pos 10993
      pos 11023
      pos 13367
    doc 11
      freq 5
      pos 532
      pos 3761
      pos 9309
      pos 9322
      pos 9707
    doc 12
      freq 18
      pos 433
      pos 4283
      pos 4633
      pos 4708
      pos 4993
      pos 5102
      pos 5207
      pos 5517
      pos 5598
      pos 5832
      pos 6430
      pos 6440
      pos 6452
      pos 6834
      pos 6850
      pos 6866
      pos 6955
      pos 6962
    doc 13
      freq 7
      pos 306
      pos 2412
      pos 2416
      pos 5651
      pos 5780
      pos 6623
      pos 6726
    doc 14
      freq 4
      pos 98
      pos 265
      pos 5275
      pos 5445
    doc 15
      freq 7
      pos 251
      pos 287
      pos 1661
      pos 1670
      pos 1681
      pos 3809
      pos 3814
    doc 16
      freq 2
      pos 1598
      pos 1607
    doc 17
      freq 9
      pos 327
      pos 535
      pos 872
      pos 897
      pos 1287
      pos 1561
      pos 2179
      pos 2219
      pos 2244
    doc 18
      freq 6
      pos 173
      pos 464
      pos 1636
      pos 2072
      pos 2097
      pos 2120
    skipList 
      level 0
        skipDoc 7
        skipDocFP 2045278
        impacts 
          impact 
            freq 8
            norm 100
          impact 
            freq 31
            norm 104
        impactsEnd 
        skipDoc 15
        skipDocFP 2047042
        impacts 
          impact 
            freq 8
            norm 95
          impact 
            freq 18
            norm 113
          impact 
            freq 19
            norm 116
        impactsEnd 
  term sedfnm234
    doc 11
      freq 1
      pos 6173
  term see
    doc 0
      freq 14
      pos 414
      pos 1226
      pos 1570
      pos 1686
      pos 1735
      pos 1786
      pos 1818
      pos 1840
      pos 1869
      pos 1893
      pos 1933
      pos 1981
      pos 2010
      pos 16731
    doc 1
      freq 2
      pos 1699
      pos 2569
    doc 3
      freq 3
      pos 1682
      pos 3189
      pos 3468
    doc 4
      freq 13
      pos 766
      pos 773
      pos 779
      pos 785
      pos 808
      pos 814
      pos 1323
      pos 1411
      pos 1710
      pos 2749
      pos 2995
      pos 3231
      pos 3534
    doc 5
      freq 9
      pos 1513
      pos 1633
      pos 1677
      pos 1913
      pos 1933
      pos 1976
      pos 2788
      pos 3949
      pos 3972
    doc 6
      freq 1
      pos 169
    doc 9
      freq 4
      pos 471
      pos 521
      pos 812
      pos 1077
    doc 10
      freq 15
      pos 2259
      pos 2460
      pos 2494
      pos 3137
      pos 3295
      pos 3777
      pos 4397
      pos 4498
      pos 5302
      pos 5439
      pos 5471
      pos 5563
      pos 6147
      pos 8309
      pos 10988
    doc 11
      freq 1
      pos 1602
    doc 12
      freq 7
      pos 785
      pos 1133
      pos 1428
      pos 2466
      pos 2882
      pos 3215
      pos 6084
    doc 13
      freq 1
      pos 3585
    doc 14
      freq 4
      pos 1794
      pos 1859
      pos 2179
      pos 2287
    doc 17
      freq 3
      pos 187
      pos 465
      pos 1902
    skipList 
      level 0
        skipDoc 10
        skipDocFP 2049158
        impacts 
          impact 
            freq 4
            norm 95
          impact 
            freq 9
            norm 104
          impact 
            freq 13
            norm 108
          impact 
            freq 15
            norm 116
        impactsEnd 
  term seed
    doc 11
      freq 2
      pos 718
      pos 9392
  term seek
    doc 2
      freq 1
      pos 1309
  term seem
    doc 10
      freq 3
      pos 8821
      pos 9606
      pos 10416
    doc 12
      freq 5
      pos 1571
      pos 1924
      pos 4363
      pos 6503
      pos 8970
  term seems
    doc 12
      freq 3
      pos 4882
      pos 6043
      pos 9288
    doc 15
      freq 3
      pos 791
      pos 1702
      pos 3118
  term seen
    doc 0
      freq 16
      pos 5989
      pos 6041
      pos 8435
      pos 8456
      pos 8503
      pos 8524
      pos 8561
      pos 8581
      pos 8619
      pos 8651
      pos 8676
      pos 8696
      pos 8721
      pos 8741
      pos 8766
      pos 8784
    doc 1
      freq 1
      pos 8354
    doc 6
      freq 1
      pos 1493
    doc 11
      freq 1
      pos 4188
    doc 12
      freq 1
      pos 5762
    doc 16
      freq 5
      pos 806
      pos 1776
      pos 1937
      pos 2157
      pos 2306
  term sees
    doc 7
      freq 1
      pos 1180
  term seg
    doc 11
      freq 1
      pos 10363
  term segment
    doc 0
      freq 1
      pos 14087
  term segmentation
    doc 13
      freq 1
      pos 2336
  term segments
    doc 13
      freq 1
      pos 2910
  term select
    doc 3
      freq 1
      pos 3343
    doc 4
      freq 2
      pos 1205
      pos 1512
    doc 5
      freq 1
      pos 3217
    doc 9
      freq 1
      pos 464
    doc 13
      freq 4
      pos 3857
      pos 4564
      pos 5265
      pos 6307
    doc 17
      freq 1
      pos 1183
  term selected
    doc 0
      freq 1
      pos 6518
    doc 1
      freq 1
      pos 4976
    doc 2
      freq 1
      pos 1351
    doc 3
      freq 1
      pos 1752
    doc 4
      freq 1
      pos 1228
    doc 5
      freq 1
      pos 1733
    doc 6
      freq 4
      pos 1045
      pos 1407
      pos 1411
      pos 2057
    doc 12
      freq 3
      pos 974
      pos 8959
      pos 8978
    doc 13
      freq 2
      pos 2968
      pos 6261
    doc 16
      freq 3
      pos 823
      pos 949
      pos 969
    skipList 
      level 0
        skipDoc 12
        skipDocFP 2052514
        impacts 
          impact 
            freq 4
            norm 101
        impactsEnd 
  term selecting
    doc 12
      freq 1
      pos 8901
    doc 13
      freq 2
      pos 3382
      pos 3696
  term selection
    doc 2
      freq 1
      pos 2311
    doc 4
      freq 1
      pos 5981
    doc 12
      freq 2
      pos 3592
      pos 7059
    doc 13
      freq 4
      pos 1007
      pos 1291
      pos 1777
      pos 1925
    doc 15
      freq 1
      pos 2578
  term self
    doc 10
      freq 7
      pos 4126
      pos 6044
      pos 6066
      pos 6081
      pos 6113
      pos 10961
      pos 11776
  term semantics
    doc 1
      freq 1
      pos 4256
    doc 11
      freq 5
      pos 388
      pos 398
      pos 1818
      pos 7004
      pos 7151
    doc 17
      freq 1
      pos 298
  term semi
    doc 10
      freq 1
      pos 4822
    doc 12
      freq 1
      pos 4388
  term semicolon
    doc 11
      freq 4
      pos 214
      pos 1379
      pos 3450
      pos 3461
  term semicolons
    doc 11
      freq 3
      pos 1229
      pos 4234
      pos 4247
  term seminars
    doc 13
      freq 1
      pos 387
  term semiur
    doc 11
      freq 2
      pos 3506
      pos 3528
  term send
    doc 0
      freq 5
      pos 5884
      pos 6090
      pos 7056
      pos 7068
      pos 13373
    doc 1
      freq 24
      pos 3797
      pos 4175
      pos 4302
      pos 4816
      pos 4947
      pos 5381
      pos 5469
      pos 5601
      pos 6230
      pos 6537
      pos 6578
      pos 6691
      pos 6889
      pos 7281
      pos 7692
      pos 7703
      pos 9440
      pos 9441
      pos 9442
      pos 9443
      pos 9444
      pos 9445
      pos 9479
      pos 9485
    doc 2
      freq 2
      pos 1412
      pos 1487
    doc 3
      freq 5
      pos 1805
      pos 1884
      pos 3559
      pos 3583
      pos 5291
    doc 4
      freq 3
      pos 4426
      pos 4455
      pos 5920
    doc 7
      freq 1
      pos 1874
    doc 9
      freq 1
      pos 1328
    doc 10
      freq 6
      pos 595
      pos 4145
      pos 6294
      pos 6922
      pos 7627
      pos 9344
    doc 12
      freq 4
      pos 3626
      pos 5691
      pos 5796
      pos 8796
    doc 13
      freq 1
      pos 4419
    doc 14
      freq 1
      pos 2746
    skipList 
      level 0
        skipDoc 10
        skipDocFP 2054305
        impacts 
          impact 
            freq 1
            norm 95
          impact 
            freq 5
            norm 107
          impact 
            freq 24
            norm 113
        impactsEnd 
  term sender
    doc 4
      freq 1
      pos 2596
    doc 5
      freq 8
      pos 133
      pos 449
      pos 494
      pos 1126
      pos 1177
      pos 1465
      pos 2329
      pos 2544
    doc 9
      freq 1
      pos 1184
    doc 10
      freq 14
      pos 830
      pos 2350
      pos 2531
      pos 2557
      pos 3030
      pos 3077
      pos 3597
      pos 3829
      pos 3905
      pos 4670
      pos 4706
      pos 8084
      pos 8108
      pos 8355
    doc 12
      freq 1
      pos 8317
    doc 13
      freq 41
      pos 279
      pos 846
      pos 861
      pos 868
      pos 993
      pos 1339
      pos 1342
      pos 1373
      pos 1384
      pos 1414
      pos 1432
      pos 1448
      pos 1477
      pos 1515
      pos 1672
      pos 2694
      pos 2875
      pos 3470
      pos 3758
      pos 4031
      pos 4252
      pos 4268
      pos 4283
      pos 4307
      pos 4318
      pos 4449
      pos 4480
      pos 4514
      pos 4536
      pos 4625
      pos 4757
      pos 4767
      pos 4787
      pos 4826
      pos 4840
      pos 4970
      pos 5411
      pos 6294
      pos 6498
      pos 6594
      pos 6595
  term sender's
    doc 1
      freq 1
      pos 4627
    doc 10
      freq 1
      pos 11219
    doc 13
      freq 1
      pos 4336
  term senders
    doc 5
      freq 1
      pos 2178
    doc 13
      freq 19
      pos 256
      pos 954
      pos 964
      pos 1400
      pos 3450
      pos 3709
      pos 3725
      pos 3784
      pos 3801
      pos 3805
      pos 5543
      pos 5669
      pos 5765
      pos 6317
      pos 6349
      pos 6377
      pos 6571
      pos 6580
      pos 6709
  term sending
    doc 0
      freq 14
      pos 7170
      pos 8391
      pos 8404
      pos 12911
      pos 13165
      pos 13267
      pos 13484
      pos 13582
      pos 13674
      pos 13776
      pos 13849
      pos 13933
      pos 14061
      pos 14190
    doc 1
      freq 9
      pos 1251
      pos 2709
      pos 3955
      pos 4275
      pos 4375
      pos 4750
      pos 5167
      pos 6388
      pos 6460
    doc 2
      freq 1
      pos 588
    doc 3
      freq 1
      pos 2591
    doc 4
      freq 5
      pos 1857
      pos 2695
      pos 4364
      pos 4532
      pos 5968
    doc 5
      freq 1
      pos 904
    doc 10
      freq 9
      pos 1314
      pos 1857
      pos 3878
      pos 3884
      pos 4539
      pos 4914
      pos 6416
      pos 7020
      pos 8970
    doc 13
      freq 1
      pos 4033
    doc 14
      freq 1
      pos 5304
    doc 16
      freq 1
      pos 407
    skipList 
      level 0
        skipDoc 13
        skipDocFP 2057288
        impacts 
          impact 
            freq 1
            norm 104
          impact 
            freq 5
            norm 108
          impact 
            freq 9
            norm 113
          impact 
            freq 14
            norm 120
        impactsEnd 
  term sends
    doc 1
      freq 2
      pos 1475
      pos 4537
    doc 5
      freq 1
      pos 2300
    doc 10
      freq 2
      pos 1837
      pos 4417
    doc 11
      freq 3
      pos 5308
      pos 5614
      pos 5780
    doc 13
      freq 2
      pos 1348
      pos 1791
  term senie
    doc 12
      freq 1
      pos 7844
  term sense
    doc 2
      freq 1
      pos 2600
    doc 3
      freq 2
      pos 4431
      pos 4475
    doc 12
      freq 5
      pos 1997
      pos 2476
      pos 5182
      pos 5201
      pos 5229
    doc 13
      freq 2
      pos 1611
      pos 3944
  term senses
    doc 10
      freq 1
      pos 9626
  term sensibl
    doc 13
      freq 1
      pos 5475
  term sensitiv
    doc 0
      freq 2
      pos 15988
      pos 16120
    doc 3
      freq 1
      pos 3322
    doc 6
      freq 3
      pos 217
      pos 335
      pos 339
    doc 10
      freq 1
      pos 5109
  term sent
    doc 0
      freq 16
      pos 3012
      pos 5842
      pos 8260
      pos 13083
      pos 13197
      pos 13286
      pos 13417
      pos 13503
      pos 13602
      pos 13692
      pos 13795
      pos 13869
      pos 13954
      pos 14082
      pos 14210
      pos 15661
    doc 1
      freq 12
      pos 3774
      pos 4317
      pos 4565
      pos 5947
      pos 6304
      pos 6340
      pos 6520
      pos 6805
      pos 6842
      pos 6882
      pos 8391
      pos 9463
    doc 2
      freq 5
      pos 606
      pos 664
      pos 682
      pos 829
      pos 5750
    doc 3
      freq 4
      pos 2496
      pos 2533
      pos 2548
      pos 4284
    doc 4
      freq 11
      pos 1054
      pos 1117
      pos 1146
      pos 1731
      pos 1766
      pos 2501
      pos 2863
      pos 2932
      pos 3872
      pos 3899
      pos 3907
    doc 5
      freq 3
      pos 236
      pos 378
      pos 1422
    doc 7
      freq 1
      pos 554
    doc 10
      freq 14
      pos 921
      pos 1268
      pos 2605
      pos 2611
      pos 3489
      pos 3555
      pos 3578
      pos 3896
      pos 4965
      pos 7577
      pos 8847
      pos 9348
      pos 11571
      pos 11594
    doc 11
      freq 2
      pos 4369
      pos 8391
    doc 12
      freq 1
      pos 8149
    doc 13
      freq 4
      pos 471
      pos 905
      pos 3132
      pos 4596
    doc 16
      freq 3
      pos 396
      pos 2048
      pos 2305
    skipList 
      level 0
        skipDoc 10
        skipDocFP 2059441
        impacts 
          impact 
            freq 1
            norm 100
          impact 
            freq 3
            norm 104
          impact 
            freq 4
            norm 107
          impact 
            freq 11
            norm 108
          impact 
            freq 12
            norm 113
          impact 
            freq 14
            norm 116
          impact 
            freq 16
            norm 120
        impactsEnd 
  term seo
    doc 4
      freq 1
      pos 5427
  term separat
    doc 1
      freq 1
      pos 3013
    doc 7
      freq 1
      pos 1162
    doc 10
      freq 2
      pos 1439
      pos 5010
    doc 12
      freq 7
      pos 264
      pos 1210
      pos 2002
      pos 2005
      pos 2286
      pos 2484
      pos 3957
    doc 13
      freq 1
      pos 5903
    doc 15
      freq 15
      pos 259
      pos 491
      pos 1200
      pos 1781
      pos 1825
      pos 1833
      pos 2074
      pos 2459
      pos 3048
      pos 3092
      pos 3106
      pos 3306
      pos 3428
      pos 3519
      pos 3612
  term separated
    doc 4
      freq 1
      pos 5869
    doc 6
      freq 1
      pos 2249
    doc 10
      freq 2
      pos 4900
      pos 4987
    doc 11
      freq 6
      pos 215
      pos 1239
      pos 1376
      pos 1380
      pos 3451
      pos 3462
    doc 13
      freq 1
      pos 5946
  term separately
    doc 2
      freq 2
      pos 801
      pos 4412
    doc 11
      freq 1
      pos 1241
    doc 12
      freq 3
      pos 2066
      pos 2326
      pos 8165
    doc 13
      freq 1
      pos 1256
  term separating
    doc 10
      freq 1
      pos 5246
    doc 11
      freq 2
      pos 306
      pos 5551
  term separation
    doc 12
      freq 1
      pos 8534
    doc 17
      freq 1
      pos 1485
  term separators
    doc 11
      freq 2
      pos 252
      pos 4224
  term september
    doc 0
      freq 2
      pos 16939
      pos 17170
    doc 2
      freq 10
      pos 2746
      pos 2887
      pos 2983
      pos 3156
      pos 3183
      pos 3225
      pos 3243
      pos 3261
      pos 3367
      pos 3383
    doc 3
      freq 2
      pos 4587
      pos 4659
    doc 4
      freq 1
      pos 5224
    doc 6
      freq 4
      pos 2891
      pos 2902
      pos 2949
      pos 2964
    doc 8
      freq 3
      pos 1843
      pos 1862
      pos 2097
    doc 10
      freq 1
      pos 13182
    doc 12
      freq 3
      pos 7326
      pos 7343
      pos 7406
    doc 13
      freq 1
      pos 6934
    doc 14
      freq 23
      pos 14
      pos 222
      pos 565
      pos 849
      pos 1226
      pos 1555
      pos 1876
      pos 2166
      pos 2557
      pos 2911
      pos 3264
      pos 3548
      pos 3846
      pos 4142
      pos 4228
      pos 4293
      pos 4415
      pos 4509
      pos 4591
      pos 4969
      pos 5197
      pos 5463
      pos 5556
    doc 16
      freq 1
      pos 2543
    skipList 
      level 0
        skipDoc 12
        skipDocFP 2062809
        impacts 
          impact 
            freq 3
            norm 97
          impact 
            freq 4
            norm 101
          impact 
            freq 10
            norm 108
        impactsEnd 
  term sequenc
    doc 0
      freq 52
      pos 683
      pos 921
      pos 1548
      pos 3035
      pos 3168
      pos 3352
      pos 3449
      pos 3521
      pos 3679
      pos 4003
      pos 4183
      pos 4456
      pos 4513
      pos 4650
      pos 4713
      pos 5408
      pos 5480
      pos 6274
      pos 6349
      pos 7172
      pos 7203
      pos 7256
      pos 7533
      pos 7557
      pos 7750
      pos 7801
      pos 8270
      pos 8343
      pos 8814
      pos 8885
      pos 9398
      pos 9488
      pos 9585
      pos 9671
      pos 9822
      pos 9897
      pos 9972
      pos 10033
      pos 10886
      pos 11039
      pos 11710
      pos 11779
      pos 11854
      pos 11986
      pos 12005
      pos 12035
      pos 12107
      pos 12185
      pos 13010
      pos 13021
      pos 13370
      pos 13382
    doc 1
      freq 9
      pos 7373
      pos 7462
      pos 7493
      pos 7507
      pos 7562
      pos 7572
      pos 7595
      pos 7660
      pos 7685
    doc 3
      freq 12
      pos 475
      pos 1366
      pos 2947
      pos 3290
      pos 3672
      pos 3723
      pos 3738
      pos 3744
      pos 3755
      pos 3765
      pos 3773
      pos 4654
    doc 4
      freq 6
      pos 3586
      pos 3634
      pos 3637
      pos 3757
      pos 3806
      pos 3809
    doc 6
      freq 1
      pos 2845
    doc 8
      freq 1
      pos 1857
    doc 9
      freq 7
      pos 835
      pos 909
      pos 1277
      pos 1295
      pos 1315
      pos 1423
      pos 1455
    doc 11
      freq 2
      pos 4760
      pos 4968
    doc 15
      freq 2
      pos 243
      pos 1427
    doc 17
      freq 8
      pos 787
      pos 794
      pos 798
      pos 822
      pos 2295
      pos 2302
      pos 2306
      pos 2330
    skipList 
      level 0
        skipDoc 11
        skipDocFP 2064131
        impacts 
          impact 
            freq 7
            norm 95
          impact 
            freq 12
            norm 107
          impact 
            freq 52
            norm 120
        impactsEnd 
  term sequencenumberskips
    doc 0
      freq 1
      pos 7564
  term sequencing
    doc 1
      freq 3
      pos 351
      pos 7363
      pos 7713
    doc 3
      freq 2
      pos 1632
      pos 3505
  term sequentially
    doc 16
      freq 1
      pos 682
  term serge
    doc 0
      freq 1
      pos 15952
  term serial
    doc 7
      freq 2
      pos 1966
      pos 2848
    doc 12
      freq 2
      pos 1786
      pos 3474
    doc 17
      freq 1
      pos 1743
  term series
    doc 0
      freq 1
      pos 16393
    doc 13
      freq 1
      pos 1500
  term serious
    doc 2
      freq 1
      pos 2178
    doc 12
      freq 1
      pos 1747
  term serve
    doc 13
      freq 1
      pos 5347
  term served
    doc 2
      freq 1
      pos 3571
    doc 8
      freq 5
      pos 269
      pos 576
      pos 907
      pos 1232
      pos 1413
    doc 12
      freq 1
      pos 3084
    doc 15
      freq 3
      pos 1852
      pos 2290
      pos 2757
  term server
    doc 10
      freq 23
      pos 977
      pos 1271
      pos 1365
      pos 1375
      pos 1613
      pos 1899
      pos 2080
      pos 2121
      pos 2173
      pos 2225
      pos 2424
      pos 2583
      pos 2632
      pos 3806
      pos 4697
      pos 4722
      pos 6314
      pos 6953
      pos 7793
      pos 10091
      pos 10802
      pos 12873
      pos 12891
    doc 12
      freq 34
      pos 1121
      pos 2214
      pos 2671
      pos 3184
      pos 3989
      pos 4167
      pos 4496
      pos 4579
      pos 4603
      pos 4624
      pos 4643
      pos 4655
      pos 4715
      pos 4983
      pos 5794
      pos 5818
      pos 6078
      pos 6139
      pos 6186
      pos 6197
      pos 6267
      pos 6311
      pos 6372
      pos 6387
      pos 6409
      pos 6924
      pos 7447
      pos 7764
      pos 8177
      pos 9175
      pos 9189
      pos 9345
      pos 9369
      pos 9391
    doc 13
      freq 2
      pos 1753
      pos 3264
    doc 14
      freq 1
      pos 1790
    doc 15
      freq 49
      pos 266
      pos 535
      pos 538
      pos 547
      pos 550
      pos 577
      pos 584
      pos 590
      pos 626
      pos 643
      pos 646
      pos 693
      pos 700
      pos 716
      pos 951
      pos 957
      pos 1066
      pos 1251
      pos 1270
      pos 1294
      pos 1739
      pos 1744
      pos 1813
      pos 1872
      pos 1928
      pos 2095
      pos 2155
      pos 2253
      pos 2400
      pos 2611
      pos 2616
      pos 2761
      pos 2768
      pos 2818
      pos 2833
      pos 2840
      pos 2860
      pos 2893
      pos 2910
      pos 2945
      pos 2963
      pos 2990
      pos 2996
      pos 3147
      pos 3286
      pos 3377
      pos 3610
      pos 3623
      pos 3788
    doc 16
      freq 23
      pos 110
      pos 129
      pos 161
      pos 196
      pos 213
      pos 225
      pos 270
      pos 446
      pos 512
      pos 873
      pos 924
      pos 937
      pos 945
      pos 958
      pos 1046
      pos 1097
      pos 1184
      pos 1361
      pos 1388
      pos 1404
      pos 1911
      pos 2268
      pos 2473
    doc 18
      freq 2
      pos 1044
      pos 1265
  term server's
    doc 12
      freq 1
      pos 2684
  term servers
    doc 10
      freq 10
      pos 222
      pos 4384
      pos 4678
      pos 4684
      pos 4746
      pos 9236
      pos 10861
      pos 11154
      pos 12936
      pos 13163
    doc 12
      freq 19
      pos 220
      pos 316
      pos 936
      pos 1130
      pos 1626
      pos 1669
      pos 1682
      pos 2199
      pos 3145
      pos 3165
      pos 3201
      pos 3496
      pos 4023
      pos 4698
      pos 4737
      pos 7065
      pos 8024
      pos 8031
      pos 8055
    doc 13
      freq 1
      pos 921
    doc 14
      freq 1
      pos 101
    doc 15
      freq 36
      pos 162
      pos 261
      pos 884
      pos 893
      pos 984
      pos 1317
      pos 1335
      pos 1602
      pos 1714
      pos 1785
      pos 1827
      pos 1837
      pos 1856
      pos 1945
      pos 1955
      pos 2003
      pos 2063
      pos 2075
      pos 2105
      pos 2269
      pos 2280
      pos 2444
      pos 2463
      pos 2570
      pos 2708
      pos 2733
      pos 2779
      pos 2814
      pos 3049
      pos 3240
      pos 3434
      pos 3470
      pos 3486
      pos 3616
      pos 3631
      pos 3705
    doc 18
      freq 5
      pos 126
      pos 951
      pos 1661
      pos 1676
      pos 1704
  term serves
    doc 1
      freq 2
      pos 1457
      pos 3132
    doc 10
      freq 2
      pos 8408
      pos 8588
  term servic
    doc 0
      freq 4
      pos 1417
      pos 16022
      pos 16454
      pos 16910
    doc 1
      freq 12
      pos 614
      pos 1014
      pos 1049
      pos 1051
      pos 1072
      pos 1074
      pos 1079
      pos 2037
      pos 2178
      pos 8025
      pos 8040
      pos 8989
    doc 2
      freq 5
      pos 3031
      pos 3130
      pos 3147
      pos 3177
      pos 6177
    doc 3
      freq 48
      pos 120
      pos 159
      pos 518
      pos 540
      pos 589
      pos 602
      pos 603
      pos 631
      pos 634
      pos 645
      pos 690
      pos 727
      pos 850
      pos 937
      pos 968
      pos 1030
      pos 1272
      pos 1282
      pos 1303
      pos 1327
      pos 1356
      pos 1673
      pos 1821
      pos 1919
      pos 2353
      pos 2369
      pos 2380
      pos 2398
      pos 2441
      pos 2472
      pos 2491
      pos 2502
      pos 2555
      pos 2575
      pos 2613
      pos 2650
      pos 2679
      pos 2751
      pos 2792
      pos 2795
      pos 3874
      pos 3958
      pos 3963
      pos 4027
      pos 4046
      pos 5042
      pos 5453
      pos 5677
    doc 4
      freq 4
      pos 4361
      pos 4416
      pos 4469
      pos 4549
    doc 5
      freq 3
      pos 316
      pos 3284
      pos 3461
    doc 6
      freq 9
      pos 319
      pos 437
      pos 886
      pos 945
      pos 2807
      pos 2925
      pos 2946
      pos 2961
      pos 2998
    doc 7
      freq 6
      pos 1108
      pos 1122
      pos 2416
      pos 2756
      pos 2781
      pos 2854
    doc 8
      freq 3
      pos 669
      pos 1879
      pos 2027
    doc 10
      freq 93
      pos 197
      pos 291
      pos 776
      pos 1561
      pos 1653
      pos 1771
      pos 1845
      pos 1852
      pos 2096
      pos 2110
      pos 2113
      pos 2132
      pos 2212
      pos 2243
      pos 2312
      pos 2322
      pos 2343
      pos 2356
      pos 2390
      pos 2449
      pos 2469
      pos 2501
      pos 2524
      pos 2553
      pos 2575
      pos 2672
      pos 2741
      pos 3089
      pos 3144
      pos 3207
      pos 3210
      pos 3266
      pos 3302
      pos 3331
      pos 3382
      pos 3575
      pos 3626
      pos 3710
      pos 3726
      pos 4356
      pos 4413
      pos 4551
      pos 4579
      pos 4729
      pos 5034
      pos 5589
      pos 5672
      pos 5873
      pos 5982
      pos 6319
      pos 6408
      pos 6437
      pos 6441
      pos 6569
      pos 6958
      pos 7012
      pos 7041
      pos 7045
      pos 7098
      pos 7287
      pos 7407
      pos 7633
      pos 7673
      pos 7693
      pos 7800
      pos 7805
      pos 7820
      pos 7846
      pos 7873
      pos 7971
      pos 7988
      pos 8959
      pos 8976
      pos 9003
      pos 9142
      pos 9214
      pos 9753
      pos 10015
      pos 10042
      pos 10060
      pos 10099
      pos 10144
      pos 10244
      pos 10285
      pos 10342
      pos 10359
      pos 10525
      pos 10539
      pos 10635
      pos 10698
      pos 10846
      pos 10936
      pos 11288
    doc 11
      freq 1
      pos 5023
    doc 12
      freq 32
      pos 101
      pos 248
      pos 256
      pos 268
      pos 1954
      pos 1968
      pos 1989
      pos 2017
      pos 2060
      pos 2069
      pos 2117
      pos 2158
      pos 2241
      pos 2246
      pos 2269
      pos 2290
      pos 2297
      pos 2308
      pos 2317
      pos 2352
      pos 2363
      pos 2366
      pos 2439
      pos 2482
      pos 2485
      pos 2501
      pos 2529
      pos 2589
      pos 2723
      pos 2739
      pos 6755
      pos 7307
    doc 13
      freq 9
      pos 327
      pos 974
      pos 1573
      pos 1685
      pos 2515
      pos 2807
      pos 2812
      pos 3539
      pos 6363
    doc 14
      freq 3
      pos 2522
      pos 2740
      pos 5298
    doc 15
      freq 7
      pos 1381
      pos 2246
      pos 2664
      pos 3348
      pos 3456
      pos 3548
      pos 3971
    doc 18
      freq 2
      pos 482
      pos 1710
    skipList 
      level 0
        skipDoc 7
        skipDocFP 2070712
        impacts 
          impact 
            freq 6
            norm 100
          impact 
            freq 9
            norm 101
          impact 
            freq 48
            norm 107
        impactsEnd 
        skipDoc 18
        skipDocFP 2072245
        impacts 
          impact 
            freq 3
            norm 97
          impact 
            freq 7
            norm 104
          impact 
            freq 9
            norm 109
          impact 
            freq 32
            norm 113
          impact 
            freq 93
            norm 116
        impactsEnd 
  term service.example.com
    doc 12
      freq 2
      pos 2311
      pos 2323
  term service.ipv6
    doc 12
      freq 1
      pos 2337
  term services
    doc 0
      freq 1
      pos 17008
    doc 1
      freq 8
      pos 108
      pos 233
      pos 1012
      pos 1919
      pos 1949
      pos 1967
      pos 1980
      pos 4468
    doc 3
      freq 7
      pos 126
      pos 197
      pos 571
      pos 731
      pos 732
      pos 1693
      pos 5114
    doc 6
      freq 1
      pos 2975
    doc 7
      freq 5
      pos 261
      pos 851
      pos 1114
      pos 2261
      pos 2773
    doc 10
      freq 19
      pos 720
      pos 1617
      pos 2274
      pos 3051
      pos 4717
      pos 5684
      pos 7909
      pos 7915
      pos 8014
      pos 8020
      pos 8165
      pos 9673
      pos 10226
      pos 10466
      pos 10681
      pos 10738
      pos 10836
      pos 10932
      pos 11150
    doc 12
      freq 10
      pos 675
      pos 2003
      pos 2041
      pos 2082
      pos 2402
      pos 2594
      pos 2760
      pos 2790
      pos 3848
      pos 7504
    doc 13
      freq 8
      pos 561
      pos 623
      pos 1010
      pos 2026
      pos 2055
      pos 2662
      pos 2822
      pos 3202
    doc 14
      freq 1
      pos 5421
    doc 15
      freq 3
      pos 682
      pos 1113
      pos 3310
    skipList 
      level 0
        skipDoc 13
        skipDocFP 2075506
        impacts 
          impact 
            freq 5
            norm 100
          impact 
            freq 7
            norm 107
          impact 
            freq 8
            norm 109
          impact 
            freq 10
            norm 113
          impact 
            freq 19
            norm 116
        impactsEnd 
  term serving
    doc 2
      freq 2
      pos 1676
      pos 1883
  term session
    doc 1
      freq 3
      pos 1832
      pos 2073
      pos 8479
    doc 3
      freq 1
      pos 1576
    doc 5
      freq 20
      pos 530
      pos 558
      pos 681
      pos 691
      pos 1382
      pos 1501
      pos 1659
      pos 1672
      pos 1946
      pos 2443
      pos 2901
      pos 2912
      pos 2921
      pos 2932
      pos 3102
      pos 3125
      pos 3533
      pos 3552
      pos 4308
      pos 4334
    doc 10
      freq 13
      pos 26
      pos 97
      pos 418
      pos 6384
      pos 6509
      pos 6684
      pos 9090
      pos 13109
      pos 13143
      pos 13157
      pos 13171
      pos 13298
      pos 13392
    doc 11
      freq 7
      pos 31
      pos 81
      pos 586
      pos 600
      pos 9319
      pos 9648
      pos 9666
    doc 12
      freq 1
      pos 9238
    doc 13
      freq 34
      pos 425
      pos 446
      pos 452
      pos 492
      pos 588
      pos 601
      pos 611
      pos 650
      pos 1162
      pos 1471
      pos 1495
      pos 1584
      pos 1589
      pos 1595
      pos 1643
      pos 1764
      pos 1945
      pos 1951
      pos 2460
      pos 3256
      pos 3293
      pos 3320
      pos 3375
      pos 4999
      pos 6181
      pos 6194
      pos 6428
      pos 6764
      pos 6779
      pos 6787
      pos 6794
      pos 6818
      pos 6847
      pos 6909
    doc 16
      freq 3
      pos 879
      pos 985
      pos 1028
    skipList 
      level 0
        skipDoc 16
        skipDocFP 2077167
        impacts 
          impact 
            freq 3
            norm 99
          impact 
            freq 20
            norm 104
          impact 
            freq 34
            norm 109
        impactsEnd 
  term sessions
    doc 3
      freq 1
      pos 5558
    doc 13
      freq 16
      pos 380
      pos 409
      pos 511
      pos 689
      pos 1297
      pos 1605
      pos 1634
      pos 1907
      pos 2426
      pos 2896
      pos 2901
      pos 3200
      pos 3247
      pos 3283
      pos 6387
      pos 6394
  term set
    doc 0
      freq 48
      pos 765
      pos 783
      pos 802
      pos 2134
      pos 2447
      pos 2962
      pos 2988
      pos 3004
      pos 3046
      pos 3273
      pos 3497
      pos 3532
      pos 3741
      pos 3745
      pos 3872
      pos 4267
      pos 4271
      pos 4372
      pos 4467
      pos 4953
      pos 4973
      pos 4987
      pos 5003
      pos 5027
      pos 5059
      pos 5079
      pos 5092
      pos 5105
      pos 5327
      pos 5342
      pos 5556
      pos 5850
      pos 5942
      pos 7119
      pos 9381
      pos 9412
      pos 9567
      pos 9611
      pos 9804
      pos 9836
      pos 11236
      pos 12565
      pos 16142
      pos 16180
      pos 16669
      pos 16788
      pos 16877
      pos 17249
    doc 1
      freq 34
      pos 193
      pos 1835
      pos 1906
      pos 2198
      pos 2813
      pos 3082
      pos 3210
      pos 3225
      pos 3803
      pos 4289
      pos 4430
      pos 4716
      pos 5150
      pos 5309
      pos 5338
      pos 5398
      pos 5424
      pos 5509
      pos 5549
      pos 5613
      pos 5841
      pos 6308
      pos 6702
      pos 6718
      pos 6730
      pos 7165
      pos 7225
      pos 8436
      pos 8502
      pos 8550
      pos 8740
      pos 8849
      pos 8859
      pos 9630
    doc 2
      freq 1
      pos 6427
    doc 3
      freq 7
      pos 392
      pos 2230
      pos 2244
      pos 3684
      pos 3706
      pos 5664
      pos 5979
    doc 4
      freq 12
      pos 109
      pos 328
      pos 1340
      pos 1724
      pos 2303
      pos 2358
      pos 2385
      pos 2462
      pos 2627
      pos 2653
      pos 2834
      pos 6134
    doc 5
      freq 8
      pos 543
      pos 1550
      pos 1771
      pos 1783
      pos 2918
      pos 3351
      pos 3478
      pos 4464
    doc 6
      freq 2
      pos 528
      pos 3264
    doc 7
      freq 3
      pos 97
      pos 472
      pos 2969
    doc 8
      freq 7
      pos 486
      pos 814
      pos 1143
      pos 1324
      pos 1514
      pos 1705
      pos 2186
    doc 9
      freq 1
      pos 1831
    doc 10
      freq 7
      pos 2857
      pos 4448
      pos 5071
      pos 5094
      pos 6795
      pos 8335
      pos 13492
    doc 11
      freq 4
      pos 738
      pos 8565
      pos 9401
      pos 10653
    doc 12
      freq 7
      pos 1468
      pos 3768
      pos 5549
      pos 8319
      pos 8475
      pos 8791
      pos 9503
    doc 13
      freq 8
      pos 620
      pos 922
      pos 1270
      pos 2798
      pos 3465
      pos 3861
      pos 5825
      pos 7118
    doc 14
      freq 2
      pos 2034
      pos 5584
    doc 15
      freq 1
      pos 4103
    doc 16
      freq 3
      pos 658
      pos 810
      pos 2714
    doc 17
      freq 4
      pos 306
      pos 1156
      pos 1528
      pos 2438
    doc 18
      freq 3
      pos 807
      pos 815
      pos 2226
    skipList 
      level 0
        skipDoc 7
        skipDocFP 2079181
        impacts 
          impact 
            freq 3
            norm 100
          impact 
            freq 8
            norm 104
          impact 
            freq 12
            norm 108
          impact 
            freq 34
            norm 113
          impact 
            freq 48
            norm 120
        impactsEnd 
        skipDoc 15
        skipDocFP 2081089
        impacts 
          impact 
            freq 1
            norm 95
          impact 
            freq 7
            norm 97
          impact 
            freq 8
            norm 109
        impactsEnd 
  term setabl
    doc 0
      freq 1
      pos 16691
  term sets
    doc 0
      freq 2
      pos 3331
      pos 3366
    doc 1
      freq 2
      pos 5476
      pos 9172
    doc 5
      freq 3
      pos 2293
      pos 2369
      pos 2423
    doc 7
      freq 2
      pos 965
      pos 2409
    doc 8
      freq 1
      pos 1753
    doc 12
      freq 1
      pos 8249
    doc 13
      freq 2
      pos 2301
      pos 2353
  term setting
    doc 0
      freq 6
      pos 2739
      pos 4935
      pos 5661
      pos 5679
      pos 6881
      pos 12771
    doc 1
      freq 8
      pos 744
      pos 946
      pos 2155
      pos 2203
      pos 2254
      pos 3776
      pos 7940
      pos 7948
    doc 3
      freq 2
      pos 1096
      pos 3908
    doc 5
      freq 1
      pos 2336
    doc 12
      freq 11
      pos 4613
      pos 6428
      pos 6449
      pos 6479
      pos 6905
      pos 8349
      pos 8563
      pos 8589
      pos 8611
      pos 8659
      pos 8893
    doc 13
      freq 1
      pos 1631
    doc 15
      freq 2
      pos 1101
      pos 1261
  term settings
    doc 0
      freq 1
      pos 5863
    doc 15
      freq 17
      pos 98
      pos 377
      pos 393
      pos 445
      pos 453
      pos 613
      pos 656
      pos 673
      pos 1085
      pos 1089
      pos 1225
      pos 1234
      pos 1248
      pos 2693
      pos 3103
      pos 3112
      pos 3327
  term setup
    doc 1
      freq 8
      pos 36
      pos 966
      pos 2862
      pos 3477
      pos 4373
      pos 6807
      pos 6912
      pos 9465
    doc 3
      freq 2
      pos 2271
      pos 4371
    doc 8
      freq 1
      pos 1799
  term sev
    doc 11
      freq 1
      pos 10199
  term seven
    doc 6
      freq 1
      pos 2090
  term seventh
    doc 12
      freq 1
      pos 698
  term sever
    doc 12
      freq 1
      pos 1656
  term several
    doc 1
      freq 3
      pos 2237
      pos 7750
      pos 7800
    doc 2
      freq 5
      pos 1370
      pos 4595
      pos 4863
      pos 5037
      pos 5124
    doc 6
      freq 1
      pos 307
    doc 7
      freq 2
      pos 1181
      pos 1639
    doc 8
      freq 2
      pos 340
      pos 386
    doc 10
      freq 3
      pos 458
      pos 1740
      pos 9624
    doc 11
      freq 12
      pos 626
      pos 878
      pos 999
      pos 1092
      pos 1595
      pos 2018
      pos 2307
      pos 4183
      pos 4748
      pos 4956
      pos 9160
      pos 9530
    doc 12
      freq 7
      pos 713
      pos 1620
      pos 1675
      pos 1907
      pos 1971
      pos 2020
      pos 3233
    doc 13
      freq 9
      pos 1065
      pos 1085
      pos 1397
      pos 2200
      pos 2792
      pos 3204
      pos 3832
      pos 3844
      pos 5157
    doc 14
      freq 1
      pos 410
    doc 16
      freq 1
      pos 2300
    doc 17
      freq 1
      pos 1331
    doc 18
      freq 2
      pos 463
      pos 1649
    skipList 
      level 0
        skipDoc 12
        skipDocFP 2084561
        impacts 
          impact 
            freq 2
            norm 97
          impact 
            freq 5
            norm 108
          impact 
            freq 7
            norm 113
          impact 
            freq 12
            norm 114
        impactsEnd 
  term sgxrnfduweeergvprjn2eda4afs9pzvxgwzlmtssmvsgctqyfgytk6
    doc 10
      freq 1
      pos 12562
  term sha1
    doc 5
      freq 6
      pos 1263
      pos 1358
      pos 2104
      pos 2126
      pos 4053
      pos 4061
    doc 10
      freq 11
      pos 5460
      pos 5485
      pos 5489
      pos 6163
      pos 6665
      pos 7380
      pos 12038
      pos 12235
      pos 12237
      pos 12250
      pos 12267
  term sha1withrsaencryption
    doc 10
      freq 3
      pos 5517
      pos 6545
      pos 7248
  term shah
    doc 1
      freq 1
      pos 8887
  term shall
    doc 0
      freq 6
      pos 958
      pos 959
      pos 2149
      pos 2203
      pos 2206
      pos 10776
    doc 1
      freq 3
      pos 1165
      pos 1166
      pos 7690
    doc 3
      freq 2
      pos 1240
      pos 1241
    doc 4
      freq 3
      pos 449
      pos 450
      pos 5613
    doc 5
      freq 3
      pos 1053
      pos 1054
      pos 1987
    doc 8
      freq 2
      pos 313
      pos 314
    doc 9
      freq 2
      pos 350
      pos 351
    doc 10
      freq 2
      pos 681
      pos 682
    doc 13
      freq 5
      pos 1189
      pos 1190
      pos 3885
      pos 5526
      pos 5544
    doc 17
      freq 8
      pos 273
      pos 274
      pos 372
      pos 622
      pos 680
      pos 770
      pos 1307
      pos 1888
    doc 18
      freq 2
      pos 388
      pos 389
    skipList 
      level 0
        skipDoc 10
        skipDocFP 2086519
        impacts 
          impact 
            freq 2
            norm 95
          impact 
            freq 3
            norm 104
          impact 
            freq 6
            norm 120
        impactsEnd 
  term shamik
    doc 0
      freq 1
      pos 15925
  term shaohu
    doc 11
      freq 1
      pos 9492
  term shaping
    doc 3
      freq 1
      pos 1010
  term share
    doc 0
      freq 1
      pos 13705
    doc 2
      freq 1
      pos 912
    doc 10
      freq 3
      pos 580
      pos 10691
      pos 10734
  term shared
    doc 1
      freq 3
      pos 3285
      pos 8712
      pos 8729
    doc 5
      freq 1
      pos 423
    doc 9
      freq 9
      pos 25
      pos 232
      pos 251
      pos 595
      pos 717
      pos 936
      pos 1372
      pos 1727
      pos 1798
    doc 10
      freq 5
      pos 891
      pos 982
      pos 993
      pos 1340
      pos 10114
    doc 12
      freq 1
      pos 6912
  term sharing
    doc 10
      freq 1
      pos 1537
    doc 12
      freq 1
      pos 3569
    doc 13
      freq 1
      pos 2636
  term sharm
    doc 3
      freq 1
      pos 4946
  term shas
    doc 11
      freq 1
      pos 9437
  term shashou
    doc 8
      freq 1
      pos 2039
  term shdnf
    doc 10
      freq 1
      pos 6860
  term she
    doc 0
      freq 1
      pos 17278
    doc 1
      freq 1
      pos 9659
    doc 2
      freq 1
      pos 6456
    doc 3
      freq 1
      pos 6008
    doc 4
      freq 1
      pos 6163
    doc 5
      freq 1
      pos 4493
    doc 6
      freq 1
      pos 3293
    doc 7
      freq 1
      pos 2998
    doc 8
      freq 2
      pos 460
      pos 2215
    doc 9
      freq 1
      pos 1860
    doc 10
      freq 6
      pos 1835
      pos 1865
      pos 1977
      pos 6300
      pos 6308
      pos 13521
    doc 11
      freq 1
      pos 10682
    doc 12
      freq 1
      pos 9532
    doc 13
      freq 1
      pos 7147
    doc 14
      freq 1
      pos 5613
    doc 15
      freq 1
      pos 4132
    doc 16
      freq 1
      pos 2743
    doc 17
      freq 1
      pos 2467
    doc 18
      freq 1
      pos 2255
    skipList 
      level 0
        skipDoc 7
        skipDocFP 2088686
        impacts 
          impact 
            freq 1
            norm 100
        impactsEnd 
        skipDoc 15
        skipDocFP 2088991
        impacts 
          impact 
            freq 1
            norm 95
          impact 
            freq 2
            norm 97
          impact 
            freq 6
            norm 116
        impactsEnd 
  term shelton
    doc 4
      freq 1
      pos 6051
  term shenker
    doc 6
      freq 2
      pos 2934
      pos 2973
  term shim6
    doc 15
      freq 1
      pos 3779
  term shin
    doc 12
      freq 1
      pos 7346
  term shirron
    doc 1
      freq 1
      pos 9267
  term short
    doc 11
      freq 4
      pos 138
      pos 1201
      pos 1205
      pos 1264
    doc 12
      freq 1
      pos 1613
    doc 13
      freq 1
      pos 4135
    doc 14
      freq 1
      pos 4167
    doc 17
      freq 1
      pos 1661
  term shortag
    doc 4
      freq 1
      pos 900
  term shorten
    doc 11
      freq 1
      pos 2344
  term shorter
    doc 0
      freq 1
      pos 10682
    doc 12
      freq 2
      pos 2980
      pos 4857
    doc 14
      freq 4
      pos 919
      pos 954
      pos 973
      pos 1625
  term shortvalu
    doc 11
      freq 1
      pos 2830
  term should
    doc 0
      freq 20
      pos 558
      pos 961
      pos 962
      pos 1445
      pos 2582
      pos 2829
      pos 2878
      pos 3123
      pos 3295
      pos 3988
      pos 4034
      pos 5539
      pos 5545
      pos 5912
      pos 6105
      pos 10263
      pos 13039
      pos 14121
      pos 15852
      pos 16171
    doc 1
      freq 15
      pos 1168
      pos 1169
      pos 1855
      pos 1892
      pos 2843
      pos 4842
      pos 5345
      pos 5492
      pos 6121
      pos 6451
      pos 7148
      pos 7552
      pos 8076
      pos 8089
      pos 8136
    doc 2
      freq 6
      pos 563
      pos 662
      pos 1411
      pos 1486
      pos 1576
      pos 1877
    doc 3
      freq 5
      pos 1243
      pos 1244
      pos 1717
      pos 2628
      pos 5339
    doc 4
      freq 20
      pos 452
      pos 453
      pos 872
      pos 940
      pos 1193
      pos 1984
      pos 2231
      pos 2561
      pos 2693
      pos 3410
      pos 3681
      pos 3847
      pos 3897
      pos 4528
      pos 4805
      pos 4957
      pos 5039
      pos 5797
      pos 5854
      pos 5963
    doc 5
      freq 4
      pos 1056
      pos 1057
      pos 2055
      pos 2072
    doc 6
      freq 2
      pos 158
      pos 1459
    doc 7
      freq 9
      pos 187
      pos 244
      pos 1316
      pos 1360
      pos 1601
      pos 1621
      pos 1641
      pos 1656
      pos 1720
    doc 8
      freq 10
      pos 316
      pos 317
      pos 399
      pos 409
      pos 422
      pos 429
      pos 614
      pos 992
      pos 1286
      pos 1481
    doc 9
      freq 7
      pos 353
      pos 354
      pos 970
      pos 982
      pos 1220
      pos 1430
      pos 1537
    doc 10
      freq 29
      pos 684
      pos 685
      pos 803
      pos 919
      pos 1216
      pos 2479
      pos 2987
      pos 3099
      pos 3145
      pos 3211
      pos 3653
      pos 3941
      pos 3985
      pos 4018
      pos 4359
      pos 4486
      pos 4628
      pos 4647
      pos 5685
      pos 5697
      pos 6105
      pos 7634
      pos 10235
      pos 10299
      pos 10419
      pos 10916
      pos 10965
      pos 11591
      pos 12368
    doc 11
      freq 29
      pos 1351
      pos 2503
      pos 2664
      pos 4260
      pos 4380
      pos 4542
      pos 4579
      pos 4609
      pos 4796
      pos 5104
      pos 5421
      pos 6589
      pos 6658
      pos 6826
      pos 6956
      pos 7591
      pos 8272
      pos 8309
      pos 8414
      pos 8446
      pos 8570
      pos 8576
      pos 8584
      pos 8679
      pos 8784
      pos 8889
      pos 9164
      pos 9388
      pos 9785
    doc 12
      freq 32
      pos 803
      pos 894
      pos 1298
      pos 2262
      pos 2530
      pos 2598
      pos 2634
      pos 3174
      pos 3710
      pos 3942
      pos 4151
      pos 4236
      pos 4535
      pos 4660
      pos 4778
      pos 4854
      pos 5236
      pos 5865
      pos 6178
      pos 6274
      pos 6459
      pos 6901
      pos 8318
      pos 8326
      pos 8345
      pos 8363
      pos 8441
      pos 8479
      pos 8665
      pos 8996
      pos 9347
      pos 9393
    doc 13
      freq 18
      pos 1192
      pos 1193
      pos 2122
      pos 3176
      pos 3676
      pos 4023
      pos 4187
      pos 4221
      pos 4655
      pos 4865
      pos 4915
      pos 5596
      pos 5753
      pos 6111
      pos 6299
      pos 6411
      pos 6418
      pos 6441
    doc 14
      freq 3
      pos 1791
      pos 1809
      pos 1817
    doc 15
      freq 14
      pos 773
      pos 804
      pos 1262
      pos 1456
      pos 1732
      pos 1956
      pos 2133
      pos 3096
      pos 3124
      pos 3248
      pos 3311
      pos 3320
      pos 3438
      pos 3653
    doc 17
      freq 8
      pos 276
      pos 277
      pos 1080
      pos 1247
      pos 1254
      pos 1334
      pos 1589
      pos 1765
    doc 18
      freq 6
      pos 391
      pos 392
      pos 809
      pos 1224
      pos 1266
      pos 1737
    skipList 
      level 0
        skipDoc 7
        skipDocFP 2090824
        impacts 
          impact 
            freq 9
            norm 100
          impact 
            freq 20
            norm 108
        impactsEnd 
        skipDoc 15
        skipDocFP 2092219
        impacts 
          impact 
            freq 7
            norm 95
          impact 
            freq 10
            norm 97
          impact 
            freq 14
            norm 104
          impact 
            freq 18
            norm 109
          impact 
            freq 32
            norm 113
        impactsEnd 
  term shouldn't
    doc 11
      freq 1
      pos 6066
    doc 15
      freq 1
      pos 2378
  term show
    doc 6
      freq 1
      pos 1534
  term showing
    doc 6
      freq 1
      pos 1566
  term shown
    doc 1
      freq 2
      pos 1463
      pos 5676
    doc 2
      freq 2
      pos 1960
      pos 2043
    doc 3
      freq 1
      pos 646
    doc 5
      freq 1
      pos 1701
    doc 10
      freq 2
      pos 5073
      pos 5993
    doc 12
      freq 3
      pos 8051
      pos 8383
      pos 8395
  term shows
    doc 6
      freq 1
      pos 2455
  term shriver
    doc 2
      freq 1
      pos 3072
  term shut
    doc 15
      freq 1
      pos 1483
  term side
    doc 3
      freq 1
      pos 5189
    doc 15
      freq 1
      pos 3533
    doc 18
      freq 1
      pos 289
  term siemens
    doc 5
      freq 3
      pos 14
      pos 4400
      pos 4414
  term siemens.com
    doc 5
      freq 2
      pos 4411
      pos 4425
  term sig
    doc 8
      freq 3
      pos 1313
      pos 1507
      pos 2078
  term sign
    doc 10
      freq 3
      pos 4006
      pos 4305
      pos 7695
  term signal
    doc 1
      freq 1
      pos 771
    doc 4
      freq 1
      pos 4655
    doc 12
      freq 2
      pos 5037
      pos 9330
  term signaled
    doc 1
      freq 1
      pos 4728
    doc 3
      freq 1
      pos 1173
  term signaling
    doc 1
      freq 13
      pos 284
      pos 288
      pos 301
      pos 4319
      pos 4327
      pos 4450
      pos 4748
      pos 4803
      pos 4882
      pos 5000
      pos 5025
      pos 5812
      pos 5917
    doc 3
      freq 2
      pos 3602
      pos 5856
    doc 5
      freq 2
      pos 3084
      pos 3578
    doc 7
      freq 1
      pos 2664
    doc 8
      freq 1
      pos 2091
    doc 9
      freq 2
      pos 163
      pos 546
    doc 10
      freq 1
      pos 13024
    doc 13
      freq 1
      pos 4644
    skipList 
      level 0
        skipDoc 13
        skipDocFP 2096747
        impacts 
          impact 
            freq 2
            norm 95
          impact 
            freq 13
            norm 113
        impactsEnd 
  term signals
    doc 1
      freq 5
      pos 571
      pos 589
      pos 628
      pos 662
      pos 700
  term signatory
    doc 10
      freq 2
      pos 7479
      pos 7519
  term signatur
    doc 10
      freq 34
      pos 147
      pos 2029
      pos 3002
      pos 3307
      pos 3318
      pos 3615
      pos 3822
      pos 4197
      pos 4222
      pos 5503
      pos 6462
      pos 6544
      pos 6578
      pos 7087
      pos 7194
      pos 7212
      pos 7247
      pos 7296
      pos 8008
      pos 8222
      pos 8240
      pos 8332
      pos 8407
      pos 8826
      pos 8844
      pos 8892
      pos 9073
      pos 9163
      pos 9612
      pos 9630
      pos 9848
      pos 11876
      pos 11964
      pos 12047
    doc 11
      freq 1
      pos 6577
    doc 17
      freq 1
      pos 1660
  term signatures
    doc 10
      freq 1
      pos 4270
    doc 18
      freq 2
      pos 1183
      pos 1690
  term signed
    doc 5
      freq 3
      pos 233
      pos 794
      pos 2606
    doc 7
      freq 1
      pos 2764
    doc 10
      freq 26
      pos 1927
      pos 3571
      pos 4127
      pos 4131
      pos 4626
      pos 4649
      pos 4806
      pos 4809
      pos 4852
      pos 4857
      pos 4877
      pos 5416
      pos 5668
      pos 6045
      pos 6067
      pos 6082
      pos 6114
      pos 6761
      pos 7842
      pos 9768
      pos 10962
      pos 11777
      pos 11779
      pos 12246
      pos 12249
      pos 12266
    doc 11
      freq 2
      pos 3542
      pos 3745
    doc 18
      freq 7
      pos 147
      pos 348
      pos 590
      pos 762
      pos 840
      pos 1779
      pos 1930
  term signed.enc
    doc 10
      freq 1
      pos 12259
  term signer
    doc 10
      freq 2
      pos 165
      pos 4167
  term significanc
    doc 3
      freq 2
      pos 1746
      pos 2686
    doc 12
      freq 1
      pos 1319
    doc 14
      freq 1
      pos 1898
  term significant
    doc 1
      freq 1
      pos 8373
    doc 2
      freq 3
      pos 804
      pos 4418
      pos 4830
    doc 3
      freq 2
      pos 284
      pos 4749
    doc 6
      freq 3
      pos 482
      pos 966
      pos 2367
    doc 7
      freq 2
      pos 241
      pos 285
    doc 10
      freq 3
      pos 9593
      pos 9619
      pos 10882
    doc 11
      freq 1
      pos 9549
    doc 12
      freq 1
      pos 1803
    doc 13
      freq 1
      pos 2043
    doc 14
      freq 36
      pos 747
      pos 778
      pos 785
      pos 799
      pos 813
      pos 820
      pos 853
      pos 964
      pos 990
      pos 1005
      pos 1012
      pos 1068
      pos 1273
      pos 1410
      pos 1438
      pos 1483
      pos 1490
      pos 1504
      pos 1513
      pos 1587
      pos 1614
      pos 1642
      pos 1657
      pos 1664
      pos 1720
      pos 1731
      pos 3231
      pos 3269
      pos 3275
      pos 4308
      pos 4431
      pos 4438
      pos 4990
      pos 4996
      pos 5013
      pos 5165
    skipList 
      level 0
        skipDoc 12
        skipDocFP 2099433
        impacts 
          impact 
            freq 2
            norm 100
          impact 
            freq 3
            norm 101
        impactsEnd 
  term significantly
    doc 9
      freq 1
      pos 274
    doc 10
      freq 1
      pos 5879
  term signing
    doc 10
      freq 5
      pos 3935
      pos 5426
      pos 5513
      pos 7749
      pos 10751
    doc 14
      freq 2
      pos 546
      pos 5482
    doc 17
      freq 2
      pos 1498
      pos 1558
    doc 18
      freq 11
      pos 31
      pos 119
      pos 376
      pos 453
      pos 461
      pos 503
      pos 535
      pos 601
      pos 1655
      pos 1701
      pos 1721
  term signs
    doc 10
      freq 1
      pos 7897
  term silently
    doc 0
      freq 1
      pos 7339
    doc 1
      freq 1
      pos 6133
    doc 3
      freq 1
      pos 1629
    doc 4
      freq 2
      pos 1429
      pos 1544
    doc 12
      freq 1
      pos 1695
  term similar
    doc 0
      freq 2
      pos 14430
      pos 14596
    doc 1
      freq 1
      pos 4760
    doc 2
      freq 1
      pos 1678
    doc 3
      freq 1
      pos 3827
    doc 10
      freq 1
      pos 1348
    doc 12
      freq 9
      pos 3146
      pos 3758
      pos 3783
      pos 5801
      pos 5977
      pos 6005
      pos 6132
      pos 6143
      pos 7931
    doc 13
      freq 4
      pos 610
      pos 775
      pos 1975
      pos 2943
  term similarities
    doc 15
      freq 1
      pos 1494
  term similarly
    doc 1
      freq 1
      pos 670
    doc 2
      freq 3
      pos 2108
      pos 4870
      pos 5451
    doc 7
      freq 1
      pos 649
    doc 10
      freq 2
      pos 2272
      pos 10687
    doc 12
      freq 1
      pos 9014
  term simon
    doc 2
      freq 1
      pos 2797
  term simpl
    doc 0
      freq 3
      pos 245
      pos 9519
      pos 17026
    doc 1
      freq 2
      pos 4869
      pos 5052
    doc 2
      freq 2
      pos 73
      pos 1233
    doc 4
      freq 1
      pos 1960
    doc 10
      freq 1
      pos 853
    doc 12
      freq 3
      pos 5491
      pos 6401
      pos 7101
    doc 15
      freq 1
      pos 1924
  term simpler
    doc 2
      freq 1
      pos 4193
    doc 12
      freq 5
      pos 5440
      pos 5573
      pos 5605
      pos 6307
      pos 6434
    doc 14
      freq 2
      pos 1163
      pos 1848
  term simplicity
    doc 15
      freq 1
      pos 2392
  term simplifications
    doc 15
      freq 1
      pos 2100
  term simplified
    doc 4
      freq 1
      pos 5977
  term simplify
    doc 1
      freq 1
      pos 2667
  term simplistic
    doc 11
      freq 1
      pos 7362
  term simply
    doc 1
      freq 1
      pos 3754
    doc 3
      freq 1
      pos 5365
    doc 10
      freq 1
      pos 10275
    doc 11
      freq 9
      pos 4559
      pos 5014
      pos 6590
      pos 6957
      pos 7961
      pos 8010
      pos 8289
      pos 8415
      pos 9399
    doc 13
      freq 1
      pos 4759
    doc 15
      freq 1
      pos 1460
    doc 18
      freq 1
      pos 327
  term simpson
    doc 2
      freq 1
      pos 3025
    doc 4
      freq 2
      pos 5200
      pos 5477
  term simultaneously
    doc 13
      freq 1
      pos 3726
    doc 15
      freq 1
      pos 473
  term sinbe6epsnawfjngp36ot2b
    doc 10
      freq 1
      pos 12578
  term since
    doc 0
      freq 6
      pos 6154
      pos 9279
      pos 9344
      pos 11992
      pos 13037
      pos 15860
    doc 1
      freq 3
      pos 5320
      pos 5835
      pos 7539
    doc 2
      freq 16
      pos 59
      pos 205
      pos 921
      pos 951
      pos 1646
      pos 1981
      pos 3626
      pos 3773
      pos 4838
      pos 4954
      pos 5265
      pos 5643
      pos 5694
      pos 5723
      pos 5923
      pos 6110
    doc 3
      freq 3
      pos 1437
      pos 5172
      pos 5222
    doc 4
      freq 2
      pos 276
      pos 5541
    doc 5
      freq 4
      pos 1133
      pos 2807
      pos 3239
      pos 3337
    doc 7
      freq 1
      pos 218
    doc 10
      freq 10
      pos 824
      pos 2174
      pos 7397
      pos 7555
      pos 7806
      pos 7999
      pos 8784
      pos 8905
      pos 9188
      pos 9805
    doc 11
      freq 8
      pos 1396
      pos 2627
      pos 6327
      pos 6391
      pos 6500
      pos 7616
      pos 8986
      pos 9047
    doc 13
      freq 7
      pos 1050
      pos 1740
      pos 1979
      pos 3420
      pos 4333
      pos 4855
      pos 4929
    doc 15
      freq 3
      pos 2747
      pos 2894
      pos 2923
    doc 16
      freq 2
      pos 369
      pos 972
    doc 17
      freq 1
      pos 1338
    doc 18
      freq 3
      pos 930
      pos 1686
      pos 1974
    skipList 
      level 0
        skipDoc 10
        skipDocFP 2103832
        impacts 
          impact 
            freq 1
            norm 100
          impact 
            freq 4
            norm 104
          impact 
            freq 16
            norm 108
        impactsEnd 
  term singh
    doc 11
      freq 1
      pos 9535
  term singl
    doc 0
      freq 5
      pos 470
      pos 1716
      pos 7874
      pos 16206
      pos 16344
    doc 1
      freq 6
      pos 1298
      pos 2879
      pos 3571
      pos 5157
      pos 5383
      pos 8858
    doc 2
      freq 2
      pos 1653
      pos 1875
    doc 3
      freq 5
      pos 818
      pos 1916
      pos 2633
      pos 3968
      pos 3982
    doc 4
      freq 1
      pos 1794
    doc 6
      freq 2
      pos 2080
      pos 2106
    doc 10
      freq 6
      pos 1714
      pos 4990
      pos 8554
      pos 10461
      pos 11949
      pos 12031
    doc 11
      freq 5
      pos 450
      pos 896
      pos 3214
      pos 3225
      pos 8078
    doc 12
      freq 2
      pos 886
      pos 8091
    doc 13
      freq 5
      pos 886
      pos 3756
      pos 5221
      pos 5445
      pos 5480
    doc 14
      freq 6
      pos 756
      pos 933
      pos 1131
      pos 1447
      pos 2248
      pos 3241
    doc 15
      freq 12
      pos 264
      pos 524
      pos 1862
      pos 1871
      pos 2251
      pos 2399
      pos 2403
      pos 3373
      pos 3451
      pos 3622
      pos 3638
      pos 3649
    doc 16
      freq 3
      pos 238
      pos 299
      pos 569
    doc 17
      freq 1
      pos 361
    doc 18
      freq 1
      pos 1287
    skipList 
      level 0
        skipDoc 11
        skipDocFP 2105540
        impacts 
          impact 
            freq 2
            norm 101
          impact 
            freq 5
            norm 107
          impact 
            freq 6
            norm 113
        impactsEnd 
  term singlepart
    doc 10
      freq 2
      pos 239
      pos 6186
  term sinha
    doc 6
      freq 1
      pos 3114
  term sinks
    doc 13
      freq 1
      pos 875
  term sinnreich
    doc 10
      freq 1
      pos 12120
    doc 11
      freq 1
      pos 9567
  term sip
    doc 5
      freq 2
      pos 2915
      pos 4333
    doc 10
      freq 186
      pos 29
      pos 100
      pos 114
      pos 131
      pos 140
      pos 174
      pos 398
      pos 421
      pos 437
      pos 462
      pos 485
      pos 524
      pos 547
      pos 588
      pos 709
      pos 717
      pos 789
      pos 833
      pos 869
      pos 901
      pos 925
      pos 1114
      pos 1213
      pos 1225
      pos 1252
      pos 1263
      pos 1310
      pos 1432
      pos 1460
      pos 1474
      pos 1544
      pos 1565
      pos 1585
      pos 1591
      pos 1687
      pos 1703
      pos 1947
      pos 1985
      pos 2090
      pos 2105
      pos 2156
      pos 2193
      pos 2236
      pos 2251
      pos 2283
      pos 2337
      pos 2382
      pos 2384
      pos 2516
      pos 2580
      pos 2677
      pos 2787
      pos 2820
      pos 2862
      pos 2971
      pos 3375
      pos 3517
      pos 3787
      pos 3802
      pos 3812
      pos 4016
      pos 4186
      pos 4322
      pos 4330
      pos 4382
      pos 4459
      pos 4597
      pos 4693
      pos 4770
      pos 4786
      pos 4869
      pos 4885
      pos 4941
      pos 5224
      pos 5248
      pos 5335
      pos 5401
      pos 5716
      pos 5766
      pos 5961
      pos 6056
      pos 6274
      pos 6324
      pos 6327
      pos 6527
      pos 6609
      pos 6612
      pos 6754
      pos 6782
      pos 6968
      pos 6976
      pos 6979
      pos 7113
      pos 7116
      pos 7272
      pos 7326
      pos 7329
      pos 7399
      pos 7416
      pos 7445
      pos 7448
      pos 7471
      pos 7492
      pos 7503
      pos 7548
      pos 7602
      pos 7614
      pos 7644
      pos 7753
      pos 7781
      pos 7791
      pos 7831
      pos 7997
      pos 8034
      pos 8199
      pos 8236
      pos 8306
      pos 8361
      pos 8376
      pos 8393
      pos 8468
      pos 8563
      pos 8777
      pos 8988
      pos 9016
      pos 9078
      pos 9097
      pos 9113
      pos 9155
      pos 9234
      pos 9268
      pos 9293
      pos 9304
      pos 9478
      pos 9567
      pos 9671
      pos 9699
      pos 9803
      pos 9943
      pos 9967
      pos 10333
      pos 10465
      pos 10469
      pos 10592
      pos 10680
      pos 10725
      pos 10789
      pos 10820
      pos 11109
      pos 11178
      pos 11197
      pos 11206
      pos 11305
      pos 11346
      pos 11411
      pos 11459
      pos 11487
      pos 11521
      pos 11544
      pos 11560
      pos 11577
      pos 11624
      pos 11648
      pos 11719
      pos 11742
      pos 11820
      pos 11839
      pos 11855
      pos 11914
      pos 12096
      pos 12387
      pos 12534
      pos 12698
      pos 12833
      pos 13010
      pos 13083
      pos 13108
      pos 13146
      pos 13160
      pos 13162
      pos 13174
      pos 13301
      pos 13333
      pos 13369
      pos 13395
      pos 13462
    doc 11
      freq 241
      pos 34
      pos 84
      pos 93
      pos 123
      pos 191
      pos 297
      pos 324
      pos 494
      pos 572
      pos 632
      pos 776
      pos 779
      pos 821
      pos 982
      pos 1047
      pos 1189
      pos 1254
      pos 1440
      pos 1454
      pos 1483
      pos 1510
      pos 1516
      pos 1574
      pos 1898
      pos 1911
      pos 1929
      pos 1933
      pos 1955
      pos 2112
      pos 2184
      pos 2199
      pos 2202
      pos 2223
      pos 2292
      pos 2359
      pos 2384
      pos 2392
      pos 2397
      pos 2422
      pos 2544
      pos 2557
      pos 2576
      pos 2677
      pos 2700
      pos 2785
      pos 2797
      pos 2841
      pos 2920
      pos 2926
      pos 2932
      pos 2938
      pos 2944
      pos 2950
      pos 2956
      pos 2962
      pos 2968
      pos 2974
      pos 2980
      pos 2986
      pos 2992
      pos 2998
      pos 3004
      pos 3010
      pos 3016
      pos 3022
      pos 3028
      pos 3034
      pos 3040
      pos 3053
      pos 3060
      pos 3066
      pos 3072
      pos 3078
      pos 3084
      pos 3090
      pos 3096
      pos 3102
      pos 3108
      pos 3114
      pos 3120
      pos 3126
      pos 3133
      pos 3153
      pos 3215
      pos 3250
      pos 3269
      pos 3320
      pos 3331
      pos 3354
      pos 3366
      pos 3388
      pos 3443
      pos 3513
      pos 3544
      pos 3548
      pos 3616
      pos 3639
      pos 3647
      pos 3655
      pos 3663
      pos 3671
      pos 3688
      pos 3766
      pos 3774
      pos 3778
      pos 3795
      pos 3884
      pos 3985
      pos 3995
      pos 4010
      pos 4127
      pos 4134
      pos 4171
      pos 4274
      pos 4294
      pos 4411
      pos 4450
      pos 4474
      pos 4654
      pos 4666
      pos 4687
      pos 4892
      pos 4903
      pos 4906
      pos 5020
      pos 5027
      pos 5070
      pos 5154
      pos 5181
      pos 5237
      pos 5315
      pos 5337
      pos 5394
      pos 5402
      pos 5441
      pos 5456
      pos 5482
      pos 5542
      pos 5621
      pos 5642
      pos 5702
      pos 5724
      pos 5788
      pos 5794
      pos 5834
      pos 5844
      pos 5853
      pos 5934
      pos 5964
      pos 6022
      pos 6050
      pos 6156
      pos 6178
      pos 6246
      pos 6266
      pos 6346
      pos 6367
      pos 6437
      pos 6440
      pos 6482
      pos 6599
      pos 6602
      pos 6676
      pos 6679
      pos 6718
      pos 6766
      pos 6787
      pos 6858
      pos 6882
      pos 6932
      pos 6963
      pos 6972
      pos 7103
      pos 7117
      pos 7142
      pos 7210
      pos 7216
      pos 7270
      pos 7302
      pos 7379
      pos 7399
      pos 7437
      pos 7448
      pos 7510
      pos 7530
      pos 7548
      pos 7626
      pos 7638
      pos 7661
      pos 7736
      pos 7763
      pos 7782
      pos 7849
      pos 7874
      pos 8029
      pos 8040
      pos 8060
      pos 8125
      pos 8132
      pos 8226
      pos 8318
      pos 8321
      pos 8458
      pos 8467
      pos 8472
      pos 8479
      pos 8556
      pos 8604
      pos 8621
      pos 8642
      pos 8727
      pos 8730
      pos 8756
      pos 8817
      pos 8820
      pos 8846
      pos 8861
      pos 8916
      pos 8937
      pos 8960
      pos 9049
      pos 9067
      pos 9095
      pos 9205
      pos 9247
      pos 9250
      pos 9255
      pos 9268
      pos 9318
      pos 9415
      pos 9522
      pos 9647
      pos 9695
      pos 9706
      pos 9722
      pos 9860
      pos 10026
      pos 10216
      pos 10425
      pos 10518
      pos 10621
    doc 13
      freq 7
      pos 1177
      pos 1598
      pos 1635
      pos 1828
      pos 1831
      pos 6846
      pos 6912
  term sip's
    doc 11
      freq 2
      pos 596
      pos 7683
  term sip.example.com
    doc 10
      freq 2
      pos 10493
      pos 10512
  term sip1
    doc 10
      freq 1
      pos 10636
    doc 11
      freq 1
      pos 3129
  term sip10
    doc 11
      freq 1
      pos 3075
  term sip11
    doc 11
      freq 1
      pos 3069
  term sip12
    doc 11
      freq 1
      pos 3063
  term sip13
    doc 11
      freq 1
      pos 3043
  term sip14
    doc 11
      freq 1
      pos 3037
  term sip15
    doc 11
      freq 1
      pos 3031
  term sip16
    doc 11
      freq 1
      pos 3025
  term sip17
    doc 11
      freq 1
      pos 3019
  term sip18
    doc 11
      freq 1
      pos 3013
  term sip19
    doc 11
      freq 1
      pos 3007
  term sip2
    doc 11
      freq 1
      pos 3123
  term sip20
    doc 11
      freq 1
      pos 3001
  term sip21
    doc 11
      freq 1
      pos 2995
  term sip22
    doc 11
      freq 1
      pos 2989
  term sip23
    doc 11
      freq 1
      pos 2983
  term sip24
    doc 11
      freq 1
      pos 2977
  term sip25
    doc 11
      freq 1
      pos 2971
  term sip26
    doc 11
      freq 1
      pos 2965
  term sip27
    doc 11
      freq 1
      pos 2959
  term sip28
    doc 11
      freq 1
      pos 2953
  term sip29
    doc 11
      freq 1
      pos 2947
  term sip3
    doc 11
      freq 1
      pos 3117
  term sip30
    doc 11
      freq 1
      pos 2941
  term sip31
    doc 11
      freq 1
      pos 2935
  term sip32
    doc 11
      freq 1
      pos 2929
  term sip33
    doc 11
      freq 1
      pos 2923
  term sip4
    doc 11
      freq 1
      pos 3111
  term sip5
    doc 11
      freq 1
      pos 3105
  term sip6
    doc 11
      freq 1
      pos 3099
  term sip7
    doc 11
      freq 1
      pos 3093
  term sip8
    doc 11
      freq 1
      pos 3087
  term sip9
    doc 11
      freq 1
      pos 3081
  term sip:a.g.bell
    doc 11
      freq 3
      pos 6454
      pos 6615
      pos 6691
  term sip:alias1
    doc 11
      freq 1
      pos 2592
  term sip:alias2
    doc 11
      freq 2
      pos 2491
      pos 2597
  term sip:alias3
    doc 11
      freq 1
      pos 2601
  term sip:alic
    doc 10
      freq 17
      pos 453
      pos 929
      pos 1811
      pos 3032
      pos 6340
      pos 6363
      pos 6480
      pos 6495
      pos 6625
      pos 6648
      pos 6973
      pos 6996
      pos 7110
      pos 7133
      pos 7232
      pos 7323
      pos 7346
  term sip:anonymous
    doc 10
      freq 2
      pos 2981
      pos 7838
  term sip:beer.example.com
    doc 11
      freq 1
      pos 1163
  term sip:bob
    doc 10
      freq 10
      pos 1817
      pos 6322
      pos 6336
      pos 6482
      pos 6607
      pos 6621
      pos 6990
      pos 7127
      pos 7230
      pos 7340
  term sip:cal
    doc 11
      freq 1
      pos 2234
  term sip:caller
    doc 11
      freq 37
      pos 2684
      pos 3372
      pos 3519
      pos 3622
      pos 4280
      pos 4459
      pos 4464
      pos 4675
      pos 4694
      pos 5163
      pos 5174
      pos 5321
      pos 5342
      pos 5466
      pos 5490
      pos 5630
      pos 5650
      pos 5940
      pos 5948
      pos 6162
      pos 6194
      pos 6772
      pos 6864
      pos 6879
      pos 7109
      pos 7385
      pos 7516
      pos 7742
      pos 7852
      pos 7859
      pos 8128
      pos 8156
      pos 8167
      pos 8178
      pos 8610
      pos 9073
      pos 9077
  term sip:example.com
    doc 11
      freq 9
      pos 2358
      pos 3330
      pos 4902
      pos 6345
      pos 7637
      pos 8039
      pos 8726
      pos 8816
      pos 8915
  term sip:fluffy
    doc 11
      freq 2
      pos 3811
      pos 3818
  term sip:i
    doc 11
      freq 1
      pos 2207
  term sip:j.user
    doc 11
      freq 13
      pos 3334
      pos 3337
      pos 3348
      pos 4277
      pos 4456
      pos 4672
      pos 5144
      pos 5160
      pos 6769
      pos 6861
      pos 7856
      pos 8043
      pos 8046
  term sip:j_user
    doc 11
      freq 3
      pos 3516
      pos 7739
      pos 9070
  term sip:jdrosen
    doc 11
      freq 2
      pos 1465
      pos 1525
  term sip:jo
    doc 11
      freq 3
      pos 3364
      pos 3369
      pos 4300
  term sip:jon
    doc 10
      freq 2
      pos 10502
      pos 10626
  term sip:kumik
    doc 11
      freq 2
      pos 3772
      pos 3815
  term sip:local
    doc 11
      freq 1
      pos 5806
  term sip:mundan
    doc 11
      freq 1
      pos 1970
  term sip:null
    doc 11
      freq 2
      pos 2362
      pos 2367
  term sip:other
    doc 11
      freq 3
      pos 5041
      pos 8164
      pos 8332
  term sip:realj
    doc 11
      freq 1
      pos 5146
  term sip:registrar.example.com
    doc 11
      freq 1
      pos 2556
  term sip:remot
    doc 11
      freq 2
      pos 5785
      pos 5802
  term sip:resourc
    doc 11
      freq 2
      pos 2562
      pos 2567
  term sip:services.example.com
    doc 11
      freq 1
      pos 1502
  term sip:sips
    doc 11
      freq 1
      pos 2195
  term sip:t.watson
    doc 11
      freq 5
      pos 6461
      pos 6597
      pos 6622
      pos 6674
      pos 6698
  term sip:user
    doc 11
      freq 60
      pos 2675
      pos 2680
      pos 2795
      pos 2813
      pos 3508
      pos 3614
      pos 3619
      pos 4024
      pos 4029
      pos 4041
      pos 4147
      pos 4152
      pos 4160
      pos 4272
      pos 4448
      pos 4664
      pos 4914
      pos 4917
      pos 4938
      pos 5038
      pos 5152
      pos 5313
      pos 5318
      pos 5453
      pos 5459
      pos 5619
      pos 5627
      pos 5929
      pos 5937
      pos 6154
      pos 6159
      pos 6349
      pos 6352
      pos 6375
      pos 6435
      pos 6764
      pos 6856
      pos 6985
      pos 6990
      pos 6998
      pos 7101
      pos 7106
      pos 7208
      pos 7382
      pos 7513
      pos 7734
      pos 7847
      pos 8123
      pos 8161
      pos 8316
      pos 8329
      pos 8493
      pos 8498
      pos 8510
      pos 8602
      pos 8607
      pos 8919
      pos 8922
      pos 8945
      pos 9065
  term sip:userb
    doc 11
      freq 2
      pos 9245
      pos 9262
  term sip:vivekg
    doc 11
      freq 2
      pos 1450
      pos 1457
  term sip:watson
    doc 11
      freq 4
      pos 8741
      pos 8746
      pos 8831
      pos 8836
  term sipfrag
    doc 11
      freq 1
      pos 3546
  term sipimp.org
    doc 11
      freq 1
      pos 3850
  term sipit
    doc 11
      freq 1
      pos 616
  term sipp
    doc 4
      freq 1
      pos 5461
  term sips
    doc 10
      freq 7
      pos 2386
      pos 4460
      pos 7505
      pos 7646
      pos 8459
      pos 9067
      pos 10302
    doc 11
      freq 2
      pos 2186
      pos 7628
  term sips:user
    doc 11
      freq 1
      pos 2035
  term sipstation.com
    doc 11
      freq 1
      pos 10563
  term sirkay
    doc 1
      freq 1
      pos 9298
    doc 3
      freq 1
      pos 4797
  term sirkay.com
    doc 3
      freq 1
      pos 4811
  term sisson
    doc 14
      freq 25
      pos 4
      pos 210
      pos 553
      pos 837
      pos 1214
      pos 1543
      pos 1864
      pos 2154
      pos 2545
      pos 2899
      pos 3252
      pos 3536
      pos 3834
      pos 4130
      pos 4216
      pos 4281
      pos 4403
      pos 4497
      pos 4579
      pos 4957
      pos 5185
      pos 5451
      pos 5508
      pos 5544
      pos 5877
  term site
    doc 12
      freq 16
      pos 1273
      pos 1278
      pos 5311
      pos 5318
      pos 5484
      pos 5556
      pos 6212
      pos 6239
      pos 6262
      pos 6365
      pos 6415
      pos 7321
      pos 7909
      pos 7927
      pos 7952
      pos 7973
    doc 15
      freq 7
      pos 1353
      pos 1587
      pos 2221
      pos 2274
      pos 2790
      pos 3316
      pos 3340
  term site's
    doc 12
      freq 1
      pos 5321
  term site.example.com
    doc 12
      freq 1
      pos 5353
  term sites
    doc 15
      freq 3
      pos 1564
      pos 1968
      pos 3074
  term sitting
    doc 13
      freq 1
      pos 4112
  term situation
    doc 3
      freq 1
      pos 3431
    doc 4
      freq 1
      pos 1851
    doc 10
      freq 1
      pos 9707
    doc 11
      freq 1
      pos 8253
    doc 12
      freq 2
      pos 2994
      pos 3142
    doc 13
      freq 1
      pos 4118
  term situations
    doc 1
      freq 1
      pos 7673
    doc 2
      freq 1
      pos 5911
  term six
    doc 2
      freq 1
      pos 737
  term sixth
    doc 12
      freq 1
      pos 696
  term size
    doc 0
      freq 16
      pos 1429
      pos 1494
      pos 1579
      pos 1628
      pos 1967
      pos 1990
      pos 2865
      pos 4766
      pos 12258
      pos 12513
      pos 12543
      pos 12587
      pos 12601
      pos 13986
      pos 14008
      pos 14015
    doc 1
      freq 1
      pos 3764
    doc 3
      freq 3
      pos 1598
      pos 1613
      pos 4236
    doc 4
      freq 2
      pos 2023
      pos 3369
    doc 6
      freq 7
      pos 1581
      pos 1665
      pos 1757
      pos 1789
      pos 1804
      pos 2201
      pos 2220
    doc 13
      freq 4
      pos 1313
      pos 1788
      pos 4688
      pos 4896
    doc 14
      freq 5
      pos 479
      pos 1172
      pos 2427
      pos 2825
      pos 2868
    doc 16
      freq 1
      pos 1407
    doc 17
      freq 5
      pos 788
      pos 799
      pos 1212
      pos 2296
      pos 2307
    skipList 
      level 0
        skipDoc 16
        skipDocFP 2122584
        impacts 
          impact 
            freq 1
            norm 99
          impact 
            freq 7
            norm 101
          impact 
            freq 16
            norm 120
        impactsEnd 
  term sized
    doc 3
      freq 1
      pos 4195
  term sizes
    doc 12
      freq 1
      pos 9337
    doc 13
      freq 1
      pos 4058
  term sj
    doc 6
      freq 2
      pos 1736
      pos 1752
  term sj3
    doc 1
      freq 1
      pos 9208
  term sjc
    doc 10
      freq 1
      pos 13438
  term sjci
    doc 1
      freq 1
      pos 9240
  term skepticism
    doc 10
      freq 1
      pos 11265
  term sketches
    doc 5
      freq 1
      pos 2249
  term skip
    doc 0
      freq 1
      pos 7559
  term skipped
    doc 14
      freq 1
      pos 1941
  term skipping
    doc 14
      freq 7
      pos 824
      pos 1026
      pos 1517
      pos 1678
      pos 2211
      pos 3562
      pos 4530
  term sl5wcs4noo3du5xs
    doc 11
      freq 1
      pos 10229
  term slaac
    doc 12
      freq 5
      pos 4433
      pos 4502
      pos 5438
      pos 6009
      pos 6135
  term slain
    doc 11
      freq 1
      pos 9602
  term sleep
    doc 13
      freq 1
      pos 2132
  term slightly
    doc 12
      freq 5
      pos 1893
      pos 5045
      pos 5876
      pos 6046
      pos 6359
    doc 18
      freq 1
      pos 546
  term slot
    doc 2
      freq 1
      pos 4296
  term slow
    doc 0
      freq 1
      pos 16498
    doc 13
      freq 1
      pos 2441
  term slp
    doc 13
      freq 1
      pos 2810
    doc 15
      freq 1
      pos 2249
  term small
    doc 2
      freq 1
      pos 4212
    doc 4
      freq 2
      pos 2021
      pos 3166
    doc 6
      freq 1
      pos 2528
    doc 9
      freq 1
      pos 574
    doc 13
      freq 1
      pos 2524
    doc 16
      freq 1
      pos 2144
    doc 18
      freq 1
      pos 912
  term smaller
    doc 4
      freq 1
      pos 2401
    doc 9
      freq 1
      pos 275
    doc 12
      freq 1
      pos 3767
    doc 18
      freq 2
      pos 106
      pos 1983
  term smallest
    doc 13
      freq 1
      pos 1247
  term smart
    doc 12
      freq 1
      pos 4914
  term smi
    doc 0
      freq 4
      pos 266
      pos 394
      pos 1032
      pos 15826
  term smith
    doc 0
      freq 1
      pos 17001
    doc 1
      freq 2
      pos 26
      pos 9573
    doc 2
      freq 4
      pos 2988
      pos 3163
      pos 4277
      pos 4348
    doc 3
      freq 1
      pos 4369
    doc 8
      freq 1
      pos 1793
  term smiv2
    doc 0
      freq 6
      pos 278
      pos 14419
      pos 14585
      pos 17053
      pos 17071
      pos 17089
    doc 2
      freq 1
      pos 2937
    doc 7
      freq 7
      pos 1030
      pos 1045
      pos 1066
      pos 1076
      pos 2575
      pos 2590
      pos 2650
  term smooth
    doc 12
      freq 1
      pos 3244
  term smoothly
    doc 12
      freq 1
      pos 1983
  term smtp
    doc 7
      freq 1
      pos 2853
    doc 12
      freq 4
      pos 2155
      pos 2189
      pos 2198
      pos 2211
    doc 15
      freq 1
      pos 2060
  term smtp.example.com
    doc 12
      freq 1
      pos 2187
  term sna
    doc 7
      freq 4
      pos 1027
      pos 1060
      pos 2572
      pos 2637
  term snmp
    doc 0
      freq 9
      pos 249
      pos 399
      pos 1046
      pos 2437
      pos 16163
      pos 16747
      pos 16801
      pos 16832
      pos 17030
    doc 2
      freq 10
      pos 77
      pos 1237
      pos 1256
      pos 1300
      pos 1746
      pos 3519
      pos 3684
      pos 3756
      pos 4130
      pos 4439
    doc 7
      freq 9
      pos 786
      pos 791
      pos 854
      pos 2131
      pos 2140
      pos 2191
      pos 2196
      pos 2201
      pos 2264
  term snmpadminstring
    doc 0
      freq 3
      pos 1044
      pos 4519
      pos 4585
  term snmpv1
    doc 0
      freq 3
      pos 3656
      pos 4172
      pos 11014
  term snmpv2
    doc 0
      freq 6
      pos 390
      pos 393
      pos 396
      pos 1017
      pos 1031
      pos 1041
  term snmpv2c
    doc 0
      freq 3
      pos 3657
      pos 4173
      pos 11027
  term snmpv3
    doc 0
      freq 8
      pos 3659
      pos 4175
      pos 11029
      pos 16729
      pos 16740
      pos 16751
      pos 16805
      pos 16815
  term snpa
    doc 0
      freq 19
      pos 1421
      pos 9061
      pos 10260
      pos 10296
      pos 10324
      pos 10340
      pos 10355
      pos 10399
      pos 10410
      pos 10437
      pos 10549
      pos 10641
      pos 10724
      pos 10734
      pos 10744
      pos 10749
      pos 10767
      pos 10774
      pos 11605
  term snpaaddresses
    doc 0
      freq 1
      pos 10593
  term snpamask
    doc 0
      freq 1
      pos 10703
  term snpaprefix
    doc 0
      freq 1
      pos 10787
  term snps
    doc 0
      freq 1
      pos 4770
  term so
    doc 0
      freq 12
      pos 12013
      pos 12886
      pos 13140
      pos 13242
      pos 13459
      pos 13557
      pos 13649
      pos 13751
      pos 13824
      pos 13896
      pos 14036
      pos 14165
    doc 1
      freq 2
      pos 3246
      pos 4663
    doc 2
      freq 10
      pos 1025
      pos 1860
      pos 2202
      pos 4413
      pos 5585
      pos 5845
      pos 5997
      pos 6098
      pos 6203
      pos 6242
    doc 3
      freq 1
      pos 4871
    doc 4
      freq 1
      pos 5622
    doc 6
      freq 1
      pos 2585
    doc 7
      freq 1
      pos 386
    doc 9
      freq 3
      pos 513
      pos 1364
      pos 1437
    doc 10
      freq 7
      pos 135
      pos 991
      pos 1480
      pos 2550
      pos 3665
      pos 8809
      pos 9086
    doc 11
      freq 6
      pos 2339
      pos 3494
      pos 4552
      pos 5444
      pos 6278
      pos 8282
    doc 12
      freq 10
      pos 1442
      pos 2714
      pos 3040
      pos 4799
      pos 5644
      pos 6709
      pos 8032
      pos 8255
      pos 8785
      pos 9181
    doc 13
      freq 6
      pos 2086
      pos 2205
      pos 3534
      pos 3988
      pos 4183
      pos 5709
    doc 15
      freq 4
      pos 977
      pos 2719
      pos 3031
      pos 3269
    doc 16
      freq 2
      pos 233
      pos 1917
    doc 17
      freq 3
      pos 1463
      pos 1683
      pos 1775
    doc 18
      freq 1
      pos 1619
    skipList 
      level 0
        skipDoc 9
        skipDocFP 2128410
        impacts 
          impact 
            freq 3
            norm 95
          impact 
            freq 10
            norm 108
          impact 
            freq 12
            norm 120
        impactsEnd 
        skipDoc 18
        skipDocFP 2129071
        impacts 
          impact 
            freq 1
            norm 97
          impact 
            freq 3
            norm 98
          impact 
            freq 4
            norm 104
          impact 
            freq 6
            norm 109
          impact 
            freq 10
            norm 113
        impactsEnd 
  term so17
    doc 15
      freq 1
      pos 4029
  term so4zxrn
    doc 11
      freq 1
      pos 10126
  term soa
    doc 12
      freq 1
      pos 5822
  term soap.beep
    doc 11
      freq 1
      pos 7507
  term society
    doc 0
      freq 4
      pos 86
      pos 1213
      pos 17230
      pos 17288
    doc 1
      freq 3
      pos 103
      pos 9611
      pos 9669
    doc 2
      freq 3
      pos 56
      pos 6408
      pos 6466
    doc 3
      freq 3
      pos 97
      pos 5960
      pos 6018
    doc 4
      freq 3
      pos 99
      pos 6115
      pos 6173
    doc 5
      freq 3
      pos 83
      pos 4445
      pos 4503
    doc 6
      freq 3
      pos 59
      pos 3240
      pos 3303
    doc 7
      freq 3
      pos 70
      pos 2950
      pos 3008
    doc 8
      freq 3
      pos 64
      pos 2167
      pos 2225
    doc 9
      freq 3
      pos 85
      pos 1812
      pos 1870
    doc 10
      freq 3
      pos 88
      pos 13473
      pos 13531
    doc 11
      freq 3
      pos 72
      pos 10634
      pos 10692
    doc 12
      freq 3
      pos 62
      pos 9484
      pos 9542
    doc 13
      freq 3
      pos 71
      pos 7099
      pos 7157
    doc 14
      freq 3
      pos 66
      pos 5565
      pos 5623
    doc 15
      freq 3
      pos 70
      pos 4084
      pos 4142
    doc 16
      freq 3
      pos 84
      pos 2695
      pos 2753
    doc 17
      freq 3
      pos 81
      pos 2419
      pos 2477
    doc 18
      freq 3
      pos 90
      pos 2207
      pos 2265
    skipList 
      level 0
        skipDoc 7
        skipDocFP 2130727
        impacts 
          impact 
            freq 3
            norm 100
          impact 
            freq 4
            norm 120
        impactsEnd 
        skipDoc 15
        skipDocFP 2131273
        impacts 
          impact 
            freq 3
            norm 95
        impactsEnd 
  term socks
    doc 7
      freq 3
      pos 2793
      pos 2803
      pos 2812
  term softwar
    doc 2
      freq 1
      pos 3839
    doc 9
      freq 1
      pos 538
    doc 12
      freq 1
      pos 1826
    doc 13
      freq 5
      pos 3360
      pos 3380
      pos 3520
      pos 3564
      pos 6801
    doc 17
      freq 4
      pos 1079
      pos 1147
      pos 1181
      pos 1233
  term sole
    doc 10
      freq 1
      pos 11381
  term solely
    doc 2
      freq 1
      pos 1865
  term soliciting
    doc 0
      freq 1
      pos 2639
  term solle
    doc 11
      freq 2
      pos 9587
      pos 9604
  term solo
    doc 10
      freq 1
      pos 13235
    doc 17
      freq 1
      pos 2055
  term solution
    doc 5
      freq 2
      pos 180
      pos 982
    doc 6
      freq 1
      pos 496
    doc 10
      freq 5
      pos 1452
      pos 1493
      pos 3775
      pos 11128
      pos 11133
    doc 12
      freq 6
      pos 1492
      pos 1529
      pos 1836
      pos 2435
      pos 2445
      pos 6686
    doc 13
      freq 4
      pos 1653
      pos 1870
      pos 4691
      pos 6731
    doc 15
      freq 9
      pos 1768
      pos 1829
      pos 2181
      pos 2293
      pos 2307
      pos 2341
      pos 2978
      pos 3121
      pos 3180
  term solutions
    doc 12
      freq 1
      pos 1547
    doc 13
      freq 3
      pos 6465
      pos 6692
      pos 6931
    doc 15
      freq 2
      pos 256
      pos 1761
  term solve
    doc 13
      freq 1
      pos 3775
    doc 15
      freq 1
      pos 2984
  term solved
    doc 4
      freq 1
      pos 4682
    doc 15
      freq 2
      pos 467
      pos 3127
  term solving
    doc 10
      freq 1
      pos 1587
  term some
    doc 0
      freq 10
      pos 429
      pos 2049
      pos 2084
      pos 2427
      pos 7595
      pos 12972
      pos 13812
      pos 15990
      pos 16124
      pos 16284
    doc 1
      freq 5
      pos 3172
      pos 3281
      pos 4357
      pos 4464
      pos 8581
    doc 2
      freq 3
      pos 107
      pos 4239
      pos 4690
    doc 3
      freq 2
      pos 1171
      pos 2366
    doc 4
      freq 3
      pos 2489
      pos 4602
      pos 5721
    doc 5
      freq 3
      pos 442
      pos 3181
      pos 3598
    doc 7
      freq 3
      pos 503
      pos 594
      pos 1272
    doc 9
      freq 1
      pos 603
    doc 10
      freq 22
      pos 505
      pos 1218
      pos 1304
      pos 1399
      pos 1890
      pos 1910
      pos 2561
      pos 3500
      pos 3943
      pos 4031
      pos 4361
      pos 8828
      pos 9487
      pos 10267
      pos 10464
      pos 10881
      pos 10933
      pos 10972
      pos 11061
      pos 11231
      pos 11273
      pos 11324
    doc 11
      freq 6
      pos 593
      pos 628
      pos 645
      pos 650
      pos 7319
      pos 7485
    doc 12
      freq 32
      pos 964
      pos 988
      pos 1099
      pos 1496
      pos 1647
      pos 1693
      pos 1820
      pos 1856
      pos 2081
      pos 3403
      pos 3596
      pos 3617
      pos 3926
      pos 4894
      pos 4961
      pos 4970
      pos 5038
      pos 5371
      pos 5446
      pos 5847
      pos 6654
      pos 6747
      pos 8488
      pos 8542
      pos 8555
      pos 8600
      pos 8653
      pos 8826
      pos 8976
      pos 9069
      pos 9308
      pos 9357
    doc 13
      freq 17
      pos 369
      pos 609
      pos 869
      pos 2264
      pos 2403
      pos 2410
      pos 2661
      pos 3523
      pos 3904
      pos 3912
      pos 5106
      pos 5328
      pos 5468
      pos 6140
      pos 6514
      pos 6579
      pos 6622
    doc 14
      freq 2
      pos 2446
      pos 5280
    doc 15
      freq 19
      pos 672
      pos 916
      pos 975
      pos 1003
      pos 1107
      pos 1286
      pos 1524
      pos 1536
      pos 1563
      pos 1633
      pos 1638
      pos 1883
      pos 1916
      pos 2078
      pos 2099
      pos 2123
      pos 2285
      pos 3187
      pos 3252
    doc 16
      freq 1
      pos 303
    doc 17
      freq 1
      pos 133
    doc 18
      freq 2
      pos 277
      pos 340
    skipList 
      level 0
        skipDoc 9
        skipDocFP 2134089
        impacts 
          impact 
            freq 1
            norm 95
          impact 
            freq 3
            norm 100
          impact 
            freq 5
            norm 113
          impact 
            freq 10
            norm 120
        impactsEnd 
        skipDoc 17
        skipDocFP 2134723
        impacts 
          impact 
            freq 1
            norm 98
          impact 
            freq 19
            norm 104
          impact 
            freq 32
            norm 113
        impactsEnd 
  term some_integer
    doc 11
      freq 1
      pos 1112
  term somehost.example.com
    doc 11
      freq 1
      pos 7877
  term somehow
    doc 10
      freq 1
      pos 8111
    doc 12
      freq 4
      pos 4690
      pos 4769
      pos 5800
      pos 8960
  term someon
    doc 10
      freq 2
      pos 619
      pos 9377
    doc 12
      freq 1
      pos 5137
  term something
    doc 12
      freq 3
      pos 8872
      pos 8902
      pos 8962
    doc 18
      freq 1
      pos 721
  term sometim
    doc 13
      freq 1
      pos 3595
  term sometimes
    doc 12
      freq 2
      pos 1332
      pos 8204
  term somewhat
    doc 2
      freq 1
      pos 1979
    doc 6
      freq 1
      pos 606
    doc 10
      freq 1
      pos 7688
    doc 12
      freq 2
      pos 1246
      pos 1868
    doc 13
      freq 1
      pos 4615
    doc 14
      freq 1
      pos 5329
  term sommerfeld
    doc 15
      freq 1
      pos 3983
  term sonet
    doc 1
      freq 5
      pos 595
      pos 623
      pos 677
      pos 697
      pos 8985
    doc 8
      freq 3
      pos 665
      pos 728
      pos 1875
  term song
    doc 5
      freq 2
      pos 4185
      pos 4260
  term sons
    doc 6
      freq 1
      pos 3005
  term soon
    doc 1
      freq 1
      pos 4824
    doc 12
      freq 1
      pos 5240
  term sophisticated
    doc 12
      freq 1
      pos 8964
  term sort
    doc 1
      freq 2
      pos 905
      pos 936
    doc 4
      freq 1
      pos 2490
    doc 10
      freq 8
      pos 506
      pos 7469
      pos 7865
      pos 8057
      pos 9048
      pos 9488
      pos 11274
      pos 11325
    doc 14
      freq 30
      pos 726
      pos 761
      pos 794
      pos 866
      pos 892
      pos 938
      pos 985
      pos 1022
      pos 1056
      pos 1452
      pos 1499
      pos 1541
      pos 1637
      pos 1674
      pos 1708
      pos 1746
      pos 2030
      pos 2040
      pos 2190
      pos 2200
      pos 3246
      pos 3282
      pos 3871
      pos 4315
      pos 4445
      pos 4601
      pos 5003
      pos 5020
      pos 5049
      pos 5172
  term sorts
    doc 1
      freq 1
      pos 3332
    doc 10
      freq 1
      pos 1197
  term sosens8zwyj6rckr2
    doc 11
      freq 1
      pos 10439
  term souiss
    doc 12
      freq 1
      pos 7268
  term sourc
    doc 0
      freq 7
      pos 13126
      pos 13228
      pos 13320
      pos 13445
      pos 13531
      pos 13635
      pos 13725
    doc 1
      freq 10
      pos 3467
      pos 3490
      pos 3508
      pos 8488
      pos 8495
      pos 8574
      pos 8585
      pos 8604
      pos 8619
      pos 8664
    doc 3
      freq 3
      pos 457
      pos 3385
      pos 5301
    doc 4
      freq 40
      pos 167
      pos 1059
      pos 1074
      pos 1100
      pos 1126
      pos 1176
      pos 1207
      pos 1787
      pos 1856
      pos 2156
      pos 2183
      pos 2192
      pos 2379
      pos 2398
      pos 2417
      pos 2440
      pos 2611
      pos 2822
      pos 3067
      pos 3154
      pos 3303
      pos 3420
      pos 3767
      pos 3866
      pos 3919
      pos 4151
      pos 4242
      pos 4268
      pos 4421
      pos 4441
      pos 4447
      pos 4464
      pos 4513
      pos 4527
      pos 5089
      pos 5108
      pos 5694
      pos 5696
      pos 5786
      pos 5979
    doc 5
      freq 12
      pos 96
      pos 137
      pos 208
      pos 382
      pos 476
      pos 511
      pos 2776
      pos 3067
      pos 3093
      pos 3245
      pos 4202
      pos 4268
    doc 6
      freq 1
      pos 2253
    doc 7
      freq 4
      pos 990
      pos 1072
      pos 2478
      pos 2646
    doc 10
      freq 2
      pos 3250
      pos 6005
    doc 11
      freq 1
      pos 7075
    doc 12
      freq 2
      pos 5698
      pos 6871
    skipList 
      level 0
        skipDoc 10
        skipDocFP 2139373
        impacts 
          impact 
            freq 4
            norm 100
          impact 
            freq 12
            norm 104
          impact 
            freq 40
            norm 108
        impactsEnd 
  term sources
    doc 13
      freq 1
      pos 873
    doc 15
      freq 3
      pos 876
      pos 879
      pos 1039
  term sous
    doc 17
      freq 1
      pos 2393
  term southampton
    doc 15
      freq 3
      pos 11
      pos 4020
      pos 4027
  term sp
    doc 1
      freq 2
      pos 8184
      pos 8204
    doc 5
      freq 2
      pos 277
      pos 1542
    doc 6
      freq 1
      pos 2928
    doc 10
      freq 4
      pos 4993
      pos 5008
      pos 5063
      pos 5333
    doc 11
      freq 11
      pos 305
      pos 312
      pos 3953
      pos 5550
      pos 5560
      pos 5590
      pos 5608
      pos 5709
      pos 5720
      pos 5756
      pos 5774
    doc 16
      freq 5
      pos 1477
      pos 1480
      pos 1491
      pos 1495
      pos 1514
  term space
    doc 1
      freq 7
      pos 380
      pos 1768
      pos 2648
      pos 7765
      pos 7815
      pos 7900
      pos 7918
    doc 2
      freq 1
      pos 1545
    doc 3
      freq 2
      pos 3746
      pos 3753
    doc 6
      freq 1
      pos 85
    doc 10
      freq 2
      pos 4991
      pos 5059
    doc 11
      freq 1
      pos 4097
    doc 12
      freq 9
      pos 173
      pos 611
      pos 890
      pos 1086
      pos 1093
      pos 5459
      pos 5643
      pos 5737
      pos 7966
    doc 15
      freq 3
      pos 2771
      pos 3081
      pos 3181
    skipList 
      level 0
        skipDoc 15
        skipDocFP 2141916
        impacts 
          impact 
            freq 1
            norm 101
          impact 
            freq 3
            norm 104
          impact 
            freq 9
            norm 113
        impactsEnd 
  term spaces
    doc 4
      freq 1
      pos 4774
    doc 10
      freq 1
      pos 3776
    doc 11
      freq 4
      pos 346
      pos 6383
      pos 6401
      pos 6430
  term spam
    doc 10
      freq 1
      pos 4712
  term span
    doc 14
      freq 1
      pos 324
    doc 18
      freq 4
      pos 206
      pos 1611
      pos 1942
      pos 1976
  term spanning
    doc 2
      freq 3
      pos 3593
      pos 3616
      pos 4721
    doc 3
      freq 1
      pos 1733
    doc 6
      freq 1
      pos 1048
  term spans
    doc 6
      freq 1
      pos 1989
  term spare
    doc 3
      freq 1
      pos 5711
  term sparks
    doc 5
      freq 1
      pos 4326
    doc 10
      freq 3
      pos 12114
      pos 13101
      pos 13380
    doc 11
      freq 56
      pos 4
      pos 183
      pos 486
      pos 813
      pos 1039
      pos 1246
      pos 1432
      pos 1566
      pos 1890
      pos 2104
      pos 2284
      pos 2536
      pos 2777
      pos 3045
      pos 3312
      pos 3435
      pos 3680
      pos 3876
      pos 3977
      pos 4163
      pos 4403
      pos 4646
      pos 4884
      pos 5062
      pos 5229
      pos 5386
      pos 5534
      pos 5694
      pos 5826
      pos 6014
      pos 6238
      pos 6474
      pos 6710
      pos 6924
      pos 7134
      pos 7262
      pos 7540
      pos 7774
      pos 8021
      pos 8218
      pos 8450
      pos 8634
      pos 8853
      pos 8952
      pos 9197
      pos 9407
      pos 9640
      pos 9714
      pos 9852
      pos 10018
      pos 10208
      pos 10417
      pos 10510
      pos 10528
      pos 10613
      pos 10946
    doc 13
      freq 1
      pos 6839
  term spart
    doc 18
      freq 2
      pos 9
      pos 2161
  term speaking
    doc 3
      freq 1
      pos 652
    doc 9
      freq 1
      pos 548
  term spec
    doc 10
      freq 12
      pos 3019
      pos 4919
      pos 4948
      pos 5165
      pos 5327
      pos 5329
      pos 5338
      pos 5347
      pos 5360
      pos 5374
      pos 7178
      pos 7886
    doc 11
      freq 3
      pos 349
      pos 6386
      pos 6394
  term special
    doc 2
      freq 1
      pos 1996
    doc 3
      freq 1
      pos 5293
    doc 7
      freq 1
      pos 1740
    doc 10
      freq 1
      pos 3697
    doc 11
      freq 2
      pos 1364
      pos 2327
    doc 12
      freq 9
      pos 82
      pos 188
      pos 635
      pos 1233
      pos 1247
      pos 1515
      pos 1523
      pos 1546
      pos 5285
    doc 13
      freq 1
      pos 3077
    doc 14
      freq 1
      pos 2342
    doc 16
      freq 1
      pos 1589
    skipList 
      level 0
        skipDoc 14
        skipDocFP 2144875
        impacts 
          impact 
            freq 1
            norm 100
          impact 
            freq 9
            norm 113
        impactsEnd 
  term specific
    doc 0
      freq 15
      pos 378
      pos 423
      pos 467
      pos 592
      pos 620
      pos 627
      pos 645
      pos 2426
      pos 4641
      pos 4661
      pos 5359
      pos 6265
      pos 6285
      pos 7739
      pos 7761
    doc 1
      freq 8
      pos 229
      pos 1976
      pos 2031
      pos 2776
      pos 3963
      pos 3965
      pos 5975
      pos 6205
    doc 2
      freq 7
      pos 485
      pos 1554
      pos 1567
      pos 1588
      pos 2636
      pos 2670
      pos 6159
    doc 3
      freq 14
      pos 193
      pos 211
      pos 537
      pos 1016
      pos 1689
      pos 1929
      pos 1944
      pos 2006
      pos 3249
      pos 3589
      pos 4426
      pos 5179
      pos 5561
      pos 5635
    doc 4
      freq 6
      pos 2486
      pos 2492
      pos 2672
      pos 4629
      pos 4786
      pos 5620
    doc 5
      freq 4
      pos 1557
      pos 1675
      pos 1759
      pos 2691
    doc 9
      freq 3
      pos 196
      pos 284
      pos 625
    doc 10
      freq 4
      pos 4035
      pos 8049
      pos 8137
      pos 11400
    doc 12
      freq 7
      pos 1461
      pos 2130
      pos 2208
      pos 2259
      pos 3654
      pos 4232
      pos 5721
    doc 13
      freq 15
      pos 1832
      pos 1881
      pos 2378
      pos 3681
      pos 4430
      pos 4958
      pos 5201
      pos 5257
      pos 5269
      pos 5271
      pos 5312
      pos 5330
      pos 5342
      pos 5568
      pos 6913
    doc 15
      freq 5
      pos 507
      pos 660
      pos 2089
      pos 3084
      pos 3985
    doc 16
      freq 2
      pos 864
      pos 1405
    doc 17
      freq 2
      pos 147
      pos 1278
    skipList 
      level 0
        skipDoc 10
        skipDocFP 2145596
        impacts 
          impact 
            freq 3
            norm 95
          impact 
            freq 4
            norm 104
          impact 
            freq 14
            norm 107
          impact 
            freq 15
            norm 120
        impactsEnd 
  term specifically
    doc 0
      freq 1
      pos 110
    doc 6
      freq 1
      pos 793
    doc 10
      freq 1
      pos 3409
    doc 18
      freq 1
      pos 722
  term specification
    doc 0
      freq 2
      pos 16926
      pos 17467
    doc 1
      freq 12
      pos 218
      pos 1155
      pos 2141
      pos 2235
      pos 3321
      pos 3339
      pos 3714
      pos 3731
      pos 6443
      pos 8366
      pos 8924
      pos 9848
    doc 2
      freq 16
      pos 291
      pos 301
      pos 1951
      pos 2077
      pos 2167
      pos 2685
      pos 3531
      pos 5043
      pos 5146
      pos 5152
      pos 5177
      pos 5182
      pos 5222
      pos 5256
      pos 6271
      pos 6645
    doc 3
      freq 5
      pos 183
      pos 697
      pos 1230
      pos 4622
      pos 6197
    doc 4
      freq 12
      pos 40
      pos 397
      pos 405
      pos 520
      pos 1883
      pos 4382
      pos 4642
      pos 5187
      pos 5245
      pos 5607
      pos 5938
      pos 6352
    doc 5
      freq 2
      pos 4295
      pos 4682
    doc 6
      freq 7
      pos 2315
      pos 2888
      pos 2899
      pos 2926
      pos 2941
      pos 2954
      pos 3482
    doc 7
      freq 6
      pos 783
      pos 908
      pos 2188
      pos 2372
      pos 2738
      pos 3187
    doc 8
      freq 3
      pos 112
      pos 303
      pos 2404
    doc 9
      freq 3
      pos 153
      pos 1113
      pos 2049
    doc 10
      freq 16
      pos 1604
      pos 3940
      pos 5481
      pos 5594
      pos 5640
      pos 5972
      pos 7712
      pos 8194
      pos 8493
      pos 9871
      pos 11335
      pos 11421
      pos 11424
      pos 11982
      pos 12067
      pos 13710
    doc 11
      freq 2
      pos 2652
      pos 10871
    doc 12
      freq 5
      pos 574
      pos 7044
      pos 7720
      pos 8513
      pos 9721
    doc 13
      freq 1
      pos 7336
    doc 14
      freq 3
      pos 5383
      pos 5400
      pos 5802
    doc 15
      freq 8
      pos 315
      pos 331
      pos 352
      pos 1693
      pos 2315
      pos 2638
      pos 3453
      pos 4321
    doc 16
      freq 7
      pos 268
      pos 1043
      pos 1050
      pos 1415
      pos 1461
      pos 1473
      pos 2932
    doc 17
      freq 2
      pos 983
      pos 2656
    doc 18
      freq 1
      pos 2444
    skipList 
      level 0
        skipDoc 7
        skipDocFP 2147801
        impacts 
          impact 
            freq 6
            norm 100
          impact 
            freq 7
            norm 101
          impact 
            freq 16
            norm 108
        impactsEnd 
        skipDoc 15
        skipDocFP 2148908
        impacts 
          impact 
            freq 3
            norm 95
          impact 
            freq 8
            norm 104
          impact 
            freq 16
            norm 116
        impactsEnd 
  term specifications
    doc 2
      freq 8
      pos 2540
      pos 2596
      pos 2613
      pos 2650
      pos 2684
      pos 4865
      pos 4883
      pos 6253
    doc 3
      freq 2
      pos 4444
      pos 4488
    doc 7
      freq 3
      pos 1308
      pos 1322
      pos 1333
    doc 10
      freq 1
      pos 13194
    doc 16
      freq 2
      pos 1447
      pos 2615
  term specifics
    doc 3
      freq 1
      pos 3246
    doc 13
      freq 1
      pos 4943
  term specified
    doc 0
      freq 8
      pos 2183
      pos 4074
      pos 5547
      pos 5752
      pos 10483
      pos 10601
      pos 11513
      pos 11577
    doc 1
      freq 18
      pos 190
      pos 845
      pos 1823
      pos 1877
      pos 1940
      pos 2248
      pos 2289
      pos 2324
      pos 2347
      pos 2520
      pos 2608
      pos 3842
      pos 5118
      pos 6084
      pos 6797
      pos 8287
      pos 8329
      pos 8417
    doc 2
      freq 1
      pos 1829
    doc 3
      freq 3
      pos 669
      pos 2010
      pos 2181
    doc 4
      freq 3
      pos 955
      pos 1292
      pos 3188
    doc 5
      freq 1
      pos 1201
    doc 6
      freq 1
      pos 434
    doc 7
      freq 1
      pos 166
    doc 8
      freq 10
      pos 507
      pos 624
      pos 838
      pos 935
      pos 1005
      pos 1260
      pos 1298
      pos 1455
      pos 1493
      pos 1718
    doc 9
      freq 7
      pos 175
      pos 241
      pos 763
      pos 789
      pos 1005
      pos 1528
      pos 1616
    doc 10
      freq 6
      pos 3621
      pos 3924
      pos 4898
      pos 5429
      pos 5492
      pos 5530
    doc 11
      freq 1
      pos 3605
    doc 12
      freq 1
      pos 8225
    doc 14
      freq 4
      pos 642
      pos 1837
      pos 2087
      pos 2946
    doc 15
      freq 1
      pos 2326
    doc 16
      freq 7
      pos 580
      pos 648
      pos 747
      pos 763
      pos 996
      pos 1265
      pos 1293
    doc 17
      freq 1
      pos 1721
    skipList 
      level 0
        skipDoc 7
        skipDocFP 2150965
        impacts 
          impact 
            freq 1
            norm 100
          impact 
            freq 3
            norm 107
          impact 
            freq 18
            norm 113
        impactsEnd 
        skipDoc 16
        skipDocFP 2151688
        impacts 
          impact 
            freq 7
            norm 95
          impact 
            freq 10
            norm 97
        impactsEnd 
  term specifier
    doc 16
      freq 1
      pos 798
  term specifies
    doc 0
      freq 2
      pos 34
      pos 269
    doc 1
      freq 12
      pos 51
      pos 167
      pos 1807
      pos 1900
      pos 2271
      pos 2278
      pos 3762
      pos 3961
      pos 5128
      pos 5973
      pos 6417
      pos 7932
    doc 3
      freq 4
      pos 45
      pos 133
      pos 145
      pos 1942
    doc 4
      freq 2
      pos 47
      pos 5734
    doc 5
      freq 9
      pos 31
      pos 195
      pos 1836
      pos 1845
      pos 1857
      pos 1868
      pos 3716
      pos 3938
      pos 3961
    doc 8
      freq 2
      pos 35
      pos 1681
    doc 9
      freq 1
      pos 33
    doc 10
      freq 6
      pos 36
      pos 513
      pos 1533
      pos 4767
      pos 5081
      pos 11484
    doc 12
      freq 2
      pos 1401
      pos 8302
    doc 13
      freq 1
      pos 76
    doc 14
      freq 2
      pos 1885
      pos 2356
    doc 16
      freq 2
      pos 32
      pos 1349
    doc 17
      freq 1
      pos 29
    doc 18
      freq 1
      pos 38
    skipList 
      level 0
        skipDoc 10
        skipDocFP 2153012
        impacts 
          impact 
            freq 1
            norm 95
          impact 
            freq 2
            norm 97
          impact 
            freq 9
            norm 104
          impact 
            freq 12
            norm 113
        impactsEnd 
  term specify
    doc 0
      freq 1
      pos 2113
    doc 1
      freq 9
      pos 464
      pos 562
      pos 729
      pos 776
      pos 807
      pos 1773
      pos 3140
      pos 3595
      pos 3706
    doc 2
      freq 2
      pos 37
      pos 5637
    doc 6
      freq 1
      pos 40
    doc 7
      freq 1
      pos 51
    doc 10
      freq 1
      pos 5104
    doc 11
      freq 1
      pos 53
    doc 12
      freq 1
      pos 43
    doc 13
      freq 4
      pos 52
      pos 1905
      pos 2186
      pos 4428
    doc 14
      freq 1
      pos 40
    doc 15
      freq 1
      pos 51
    doc 16
      freq 1
      pos 675
    skipList 
      level 0
        skipDoc 12
        skipDocFP 2154374
        impacts 
          impact 
            freq 1
            norm 100
          impact 
            freq 2
            norm 108
          impact 
            freq 9
            norm 113
        impactsEnd 
  term specifying
    doc 12
      freq 1
      pos 7500
    doc 14
      freq 1
      pos 5417
  term speed
    doc 2
      freq 1
      pos 3962
    doc 7
      freq 2
      pos 1942
      pos 1965
  term speeds
    doc 2
      freq 1
      pos 3725
  term spehqpfcwtvk1ytimukxwkp
    doc 11
      freq 1
      pos 10014
  term spf
    doc 0
      freq 2
      pos 5187
      pos 7696
  term spindle.example.com
    doc 11
      freq 1
      pos 1513
  term split
    doc 0
      freq 3
      pos 2490
      pos 16224
      pos 16348
    doc 12
      freq 2
      pos 4935
      pos 7959
    doc 13
      freq 1
      pos 983
    doc 15
      freq 1
      pos 3077
  term sponsor
    doc 2
      freq 1
      pos 5571
  term sponsored
    doc 0
      freq 1
      pos 17282
    doc 1
      freq 1
      pos 9663
    doc 2
      freq 1
      pos 6460
    doc 3
      freq 1
      pos 6012
    doc 4
      freq 1
      pos 6167
    doc 5
      freq 1
      pos 4497
    doc 6
      freq 1
      pos 3297
    doc 7
      freq 1
      pos 3002
    doc 8
      freq 1
      pos 2219
    doc 9
      freq 1
      pos 1864
    doc 10
      freq 1
      pos 13525
    doc 11
      freq 1
      pos 10686
    doc 12
      freq 1
      pos 9536
    doc 13
      freq 1
      pos 7151
    doc 14
      freq 1
      pos 5617
    doc 15
      freq 1
      pos 4136
    doc 16
      freq 1
      pos 2747
    doc 17
      freq 1
      pos 2471
    doc 18
      freq 1
      pos 2259
    skipList 
      level 0
        skipDoc 7
        skipDocFP 2156016
        impacts 
          impact 
            freq 1
            norm 100
        impactsEnd 
        skipDoc 15
        skipDocFP 2156321
        impacts 
          impact 
            freq 1
            norm 95
        impactsEnd 
  term spoof
    doc 15
      freq 1
      pos 1736
  term spoofabl
    doc 10
      freq 1
      pos 659
  term spoofed
    doc 1
      freq 1
      pos 8579
    doc 13
      freq 1
      pos 5763
    doc 15
      freq 1
      pos 1720
  term spoofing
    doc 1
      freq 5
      pos 8012
      pos 8226
      pos 8587
      pos 8621
      pos 8666
  term sporadic
    doc 13
      freq 1
      pos 4154
  term sporadically
    doc 13
      freq 1
      pos 883
  term sports
    doc 13
      freq 2
      pos 827
      pos 3073
  term spreading
    doc 13
      freq 1
      pos 2393
  term spring
    doc 7
      freq 1
      pos 311
  term spurious
    doc 11
      freq 1
      pos 3262
  term spurred
    doc 7
      freq 1
      pos 1408
  term sr5bz2izli5r7dkxued2fcktunnfn5cylr
    doc 11
      freq 1
      pos 9913
  term srisuresh
    doc 12
      freq 1
      pos 7476
  term srtp
    doc 5
      freq 21
      pos 161
      pos 171
      pos 215
      pos 502
      pos 516
      pos 636
      pos 963
      pos 1293
      pos 1301
      pos 1431
      pos 1511
      pos 1712
      pos 2761
      pos 2767
      pos 2794
      pos 2798
      pos 2945
      pos 2951
      pos 2958
      pos 4233
      pos 4371
  term srv
    doc 10
      freq 2
      pos 10601
      pos 10630
    doc 12
      freq 2
      pos 2090
      pos 7506
    doc 14
      freq 7
      pos 224
      pos 2509
      pos 2524
      pos 2528
      pos 2541
      pos 2675
      pos 5423
  term ss1
    doc 11
      freq 2
      pos 9265
      pos 9270
  term ssize
    doc 7
      freq 1
      pos 1936
  term ssr4b5f
    doc 11
      freq 1
      pos 10453
  term st
    doc 3
      freq 1
      pos 4922
    doc 10
      freq 1
      pos 13411
    doc 11
      freq 1
      pos 10557
    doc 12
      freq 1
      pos 9433
    doc 17
      freq 1
      pos 2377
  term stabl
    doc 9
      freq 1
      pos 927
    doc 12
      freq 1
      pos 4506
  term stack
    doc 1
      freq 7
      pos 1109
      pos 1503
      pos 1530
      pos 1757
      pos 1795
      pos 2012
      pos 8947
    doc 3
      freq 5
      pos 749
      pos 854
      pos 3371
      pos 3824
      pos 3849
    doc 8
      freq 1
      pos 2072
    doc 12
      freq 6
      pos 2662
      pos 4095
      pos 4099
      pos 4157
      pos 4185
      pos 7800
    doc 15
      freq 37
      pos 34
      pos 196
      pos 212
      pos 307
      pos 426
      pos 457
      pos 517
      pos 596
      pos 637
      pos 771
      pos 815
      pos 832
      pos 1027
      pos 1077
      pos 1380
      pos 1395
      pos 1431
      pos 1596
      pos 1755
      pos 2150
      pos 2273
      pos 2360
      pos 2423
      pos 2439
      pos 2596
      pos 2678
      pos 3008
      pos 3245
      pos 3290
      pos 3330
      pos 3344
      pos 3409
      pos 3565
      pos 3759
      pos 3804
      pos 4010
      pos 4073
  term staff
    doc 2
      freq 1
      pos 653
  term stale
    doc 10
      freq 1
      pos 8642
    doc 12
      freq 1
      pos 4813
  term stallard
    doc 6
      freq 1
      pos 3130
  term stamp
    doc 5
      freq 2
      pos 2340
      pos 2412
  term stanc
    doc 12
      freq 1
      pos 848
  term standard
    doc 0
      freq 5
      pos 144
      pos 195
      pos 210
      pos 17188
      pos 17514
    doc 1
      freq 2
      pos 4688
      pos 9895
    doc 2
      freq 14
      pos 40
      pos 1543
      pos 2015
      pos 2566
      pos 2660
      pos 2708
      pos 2860
      pos 3527
      pos 3709
      pos 3719
      pos 3787
      pos 3821
      pos 4082
      pos 6692
    doc 3
      freq 5
      pos 3149
      pos 4411
      pos 4449
      pos 5803
      pos 6244
    doc 4
      freq 1
      pos 6399
    doc 5
      freq 1
      pos 4729
    doc 6
      freq 3
      pos 43
      pos 74
      pos 3529
    doc 7
      freq 5
      pos 54
      pos 486
      pos 701
      pos 1997
      pos 3234
    doc 8
      freq 1
      pos 2451
    doc 9
      freq 1
      pos 2096
    doc 10
      freq 2
      pos 7780
      pos 13757
    doc 11
      freq 2
      pos 56
      pos 10918
    doc 12
      freq 3
      pos 46
      pos 576
      pos 9768
    doc 13
      freq 5
      pos 55
      pos 1652
      pos 1869
      pos 5274
      pos 7383
    doc 14
      freq 3
      pos 43
      pos 1804
      pos 5849
    doc 15
      freq 3
      pos 54
      pos 1701
      pos 4368
    doc 16
      freq 1
      pos 2979
    doc 17
      freq 1
      pos 2703
    doc 18
      freq 1
      pos 2491
    skipList 
      level 0
        skipDoc 7
        skipDocFP 2160282
        impacts 
          impact 
            freq 5
            norm 100
          impact 
            freq 14
            norm 108
        impactsEnd 
        skipDoc 15
        skipDocFP 2160996
        impacts 
          impact 
            freq 1
            norm 95
          impact 
            freq 3
            norm 104
          impact 
            freq 5
            norm 109
        impactsEnd 
  term standardization
    doc 0
      freq 1
      pos 67
    doc 1
      freq 1
      pos 84
    doc 3
      freq 1
      pos 78
    doc 4
      freq 1
      pos 80
    doc 5
      freq 1
      pos 64
    doc 9
      freq 1
      pos 66
    doc 10
      freq 1
      pos 69
    doc 16
      freq 1
      pos 65
    doc 17
      freq 1
      pos 62
    doc 18
      freq 1
      pos 71
    skipList 
      level 0
        skipDoc 16
        skipDocFP 2162098
        impacts 
          impact 
            freq 1
            norm 95
        impactsEnd 
  term standardized
    doc 12
      freq 2
      pos 4395
      pos 4418
  term standardizing
    doc 2
      freq 1
      pos 1289
  term standards
    doc 0
      freq 107
      pos 13
      pos 37
      pos 62
      pos 181
      pos 482
      pos 656
      pos 817
      pos 989
      pos 1198
      pos 1396
      pos 1608
      pos 1774
      pos 1915
      pos 2091
      pos 2323
      pos 2533
      pos 2714
      pos 2893
      pos 3081
      pos 3242
      pos 3453
      pos 3665
      pos 3800
      pos 4011
      pos 4196
      pos 4399
      pos 4542
      pos 4699
      pos 4815
      pos 5037
      pos 5231
      pos 5468
      pos 5582
      pos 5764
      pos 5945
      pos 6173
      pos 6338
      pos 6428
      pos 6648
      pos 6902
      pos 7081
      pos 7245
      pos 7346
      pos 7508
      pos 7673
      pos 7812
      pos 7946
      pos 8130
      pos 8325
      pos 8415
      pos 8634
      pos 8822
      pos 8922
      pos 9074
      pos 9239
      pos 9433
      pos 9589
      pos 9733
      pos 9899
      pos 10039
      pos 10165
      pos 10379
      pos 10578
      pos 10804
      pos 11016
      pos 11090
      pos 11298
      pos 11479
      pos 11637
      pos 11768
      pos 11874
      pos 12045
      pos 12172
      pos 12308
      pos 12461
      pos 12633
      pos 12781
      pos 12986
      pos 13177
      pos 13336
      pos 13536
      pos 13730
      pos 13920
      pos 14131
      pos 14318
      pos 14495
      pos 14661
      pos 14799
      pos 14919
      pos 15046
      pos 15173
      pos 15303
      pos 15414
      pos 15485
      pos 15556
      pos 15634
      pos 15718
      pos 15795
      pos 16127
      pos 16316
      pos 16468
      pos 16601
      pos 16839
      pos 16938
      pos 17097
      pos 17212
      pos 17543
    doc 1
      freq 37
      pos 13
      pos 54
      pos 79
      pos 200
      pos 423
      pos 831
      pos 1060
      pos 1368
      pos 1861
      pos 2221
      pos 2417
      pos 2691
      pos 3050
      pos 3420
      pos 3605
      pos 3902
      pos 4239
      pos 4633
      pos 5013
      pos 5292
      pos 5684
      pos 6019
      pos 6360
      pos 6755
      pos 7193
      pos 7635
      pos 7885
      pos 8233
      pos 8701
      pos 9016
      pos 9124
      pos 9220
      pos 9327
      pos 9397
      pos 9492
      pos 9593
      pos 9926
    doc 2
      freq 25
      pos 236
      pos 703
      pos 734
      pos 1373
      pos 1930
      pos 1953
      pos 2046
      pos 2061
      pos 2289
      pos 2482
      pos 2503
      pos 2558
      pos 2881
      pos 3413
      pos 3683
      pos 3760
      pos 3913
      pos 4118
      pos 4139
      pos 4210
      pos 4315
      pos 4380
      pos 4398
      pos 4481
      pos 4688
    doc 3
      freq 28
      pos 13
      pos 48
      pos 73
      pos 163
      pos 328
      pos 575
      pos 755
      pos 1034
      pos 1420
      pos 1773
      pos 2112
      pos 2423
      pos 2818
      pos 3202
      pos 3611
      pos 4005
      pos 4293
      pos 4453
      pos 4554
      pos 4735
      pos 4828
      pos 4932
      pos 4997
      pos 5193
      pos 5583
      pos 5784
      pos 5940
      pos 6275
    doc 4
      freq 29
      pos 19
      pos 50
      pos 75
      pos 136
      pos 417
      pos 737
      pos 1006
      pos 1363
      pos 1750
      pos 2072
      pos 2309
      pos 2713
      pos 2959
      pos 3196
      pos 3432
      pos 3622
      pos 3794
      pos 4084
      pos 4494
      pos 4825
      pos 4880
      pos 5018
      pos 5151
      pos 5396
      pos 5526
      pos 5811
      pos 6030
      pos 6096
      pos 6430
    doc 5
      freq 21
      pos 12
      pos 34
      pos 59
      pos 244
      pos 347
      pos 783
      pos 1140
      pos 1471
      pos 1738
      pos 2041
      pos 2352
      pos 2549
      pos 2730
      pos 3044
      pos 3354
      pos 3655
      pos 3907
      pos 4107
      pos 4343
      pos 4428
      pos 4759
    doc 6
      freq 1
      pos 78
    doc 7
      freq 15
      pos 34
      pos 83
      pos 105
      pos 175
      pos 324
      pos 343
      pos 512
      pos 1441
      pos 1492
      pos 1560
      pos 1597
      pos 1611
      pos 1634
      pos 1781
      pos 1808
    doc 8
      freq 1
      pos 289
    doc 9
      freq 10
      pos 13
      pos 36
      pos 61
      pos 226
      pos 589
      pos 930
      pos 1366
      pos 1721
      pos 1792
      pos 2125
    doc 10
      freq 49
      pos 11
      pos 39
      pos 64
      pos 168
      pos 392
      pos 783
      pos 1246
      pos 1697
      pos 2084
      pos 2510
      pos 2965
      pos 3369
      pos 3781
      pos 4180
      pos 4591
      pos 4935
      pos 5395
      pos 5468
      pos 5748
      pos 5760
      pos 6050
      pos 6268
      pos 6521
      pos 6776
      pos 6962
      pos 7266
      pos 7596
      pos 8028
      pos 8462
      pos 8982
      pos 9472
      pos 9937
      pos 10327
      pos 10783
      pos 10929
      pos 11200
      pos 11538
      pos 11833
      pos 12001
      pos 12085
      pos 12090
      pos 12381
      pos 12528
      pos 12692
      pos 12827
      pos 13077
      pos 13327
      pos 13456
      pos 13787
    doc 16
      freq 17
      pos 17
      pos 35
      pos 60
      pos 163
      pos 529
      pos 904
      pos 1309
      pos 1564
      pos 1648
      pos 1683
      pos 1851
      pos 2109
      pos 2246
      pos 2508
      pos 2637
      pos 2677
      pos 3008
    doc 17
      freq 15
      pos 11
      pos 32
      pos 57
      pos 151
      pos 497
      pos 510
      pos 810
      pos 1048
      pos 1394
      pos 1843
      pos 2108
      pos 2146
      pos 2315
      pos 2401
      pos 2733
    doc 18
      freq 11
      pos 17
      pos 41
      pos 66
      pos 241
      pos 617
      pos 1025
      pos 1380
      pos 1807
      pos 2147
      pos 2190
      pos 2521
    skipList 
      level 0
        skipDoc 7
        skipDocFP 2162779
        impacts 
          impact 
            freq 15
            norm 100
          impact 
            freq 21
            norm 104
          impact 
            freq 28
            norm 107
          impact 
            freq 29
            norm 108
          impact 
            freq 37
            norm 113
          impact 
            freq 107
            norm 120
        impactsEnd 
  term standards.ieee.org
    doc 2
      freq 2
      pos 2297
      pos 3434
  term stanley
    doc 2
      freq 3
      pos 1772
      pos 3284
      pos 6010
  term staple.example.com
    doc 11
      freq 1
      pos 7768
  term stapp
    doc 12
      freq 3
      pos 7812
      pos 7826
      pos 7861
  term start
    doc 0
      freq 3
      pos 2188
      pos 14289
      pos 14311
    doc 4
      freq 1
      pos 1023
    doc 5
      freq 1
      pos 1944
    doc 11
      freq 7
      pos 365
      pos 839
      pos 1792
      pos 5566
      pos 6725
      pos 6741
      pos 6810
    doc 12
      freq 4
      pos 3306
      pos 3334
      pos 3549
      pos 4875
    doc 13
      freq 1
      pos 3103
  term started
    doc 7
      freq 1
      pos 467
    doc 15
      freq 2
      pos 1447
      pos 1486
  term starting
    doc 0
      freq 1
      pos 1549
    doc 2
      freq 1
      pos 3790
    doc 4
      freq 1
      pos 1274
    doc 5
      freq 1
      pos 1499
    doc 7
      freq 2
      pos 491
      pos 2860
    doc 10
      freq 1
      pos 8444
    doc 12
      freq 2
      pos 3413
      pos 8027
    doc 14
      freq 1
      pos 1114
    doc 16
      freq 1
      pos 1699
    skipList 
      level 0
        skipDoc 14
        skipDocFP 2169869
        impacts 
          impact 
            freq 2
            norm 100
        impactsEnd 
  term starts
    doc 5
      freq 1
      pos 559
  term startup
    doc 15
      freq 2
      pos 242
      pos 1426
  term state
    doc 0
      freq 48
      pos 68
      pos 690
      pos 884
      pos 890
      pos 904
      pos 913
      pos 1374
      pos 1506
      pos 2124
      pos 2142
      pos 2245
      pos 2361
      pos 2504
      pos 2680
      pos 2685
      pos 2734
      pos 3113
      pos 3254
      pos 3289
      pos 3892
      pos 4392
      pos 4791
      pos 4874
      pos 4931
      pos 4941
      pos 5069
      pos 5635
      pos 5657
      pos 5663
      pos 5681
      pos 7913
      pos 8985
      pos 9017
      pos 9035
      pos 9336
      pos 9363
      pos 10117
      pos 10178
      pos 11413
      pos 11465
      pos 11837
      pos 12377
      pos 12662
      pos 12807
      pos 14215
      pos 14219
      pos 14240
      pos 16558
    doc 1
      freq 5
      pos 85
      pos 1308
      pos 4838
      pos 4908
      pos 6446
    doc 2
      freq 10
      pos 299
      pos 2075
      pos 3337
      pos 4893
      pos 5007
      pos 5116
      pos 5150
      pos 5186
      pos 5216
      pos 5304
    doc 3
      freq 1
      pos 79
    doc 4
      freq 2
      pos 81
      pos 1624
    doc 5
      freq 3
      pos 65
      pos 3304
      pos 3336
    doc 9
      freq 1
      pos 67
    doc 10
      freq 1
      pos 70
    doc 12
      freq 1
      pos 4665
    doc 13
      freq 3
      pos 4961
      pos 6373
      pos 6429
    doc 16
      freq 3
      pos 66
      pos 950
      pos 981
    doc 17
      freq 2
      pos 63
      pos 238
    doc 18
      freq 1
      pos 72
    skipList 
      level 0
        skipDoc 10
        skipDocFP 2170544
        impacts 
          impact 
            freq 1
            norm 95
          impact 
            freq 3
            norm 104
          impact 
            freq 10
            norm 108
          impact 
            freq 48
            norm 120
        impactsEnd 
  term stated
    doc 5
      freq 2
      pos 1981
      pos 2038
    doc 12
      freq 2
      pos 1046
      pos 6946
    doc 15
      freq 1
      pos 2563
  term stateless
    doc 12
      freq 7
      pos 392
      pos 4245
      pos 4430
      pos 5431
      pos 7079
      pos 7132
      pos 7301
    doc 13
      freq 1
      pos 6476
    doc 15
      freq 7
      pos 396
      pos 407
      pos 556
      pos 761
      pos 3432
      pos 3916
      pos 3965
  term statelessly
    doc 11
      freq 1
      pos 7069
  term statement
    doc 0
      freq 3
      pos 14392
      pos 14557
      pos 17225
    doc 1
      freq 1
      pos 9606
    doc 2
      freq 2
      pos 827
      pos 6403
    doc 3
      freq 3
      pos 189
      pos 1265
      pos 5955
    doc 4
      freq 1
      pos 6110
    doc 5
      freq 1
      pos 4440
    doc 6
      freq 1
      pos 3235
    doc 7
      freq 5
      pos 267
      pos 748
      pos 2101
      pos 2438
      pos 2945
    doc 8
      freq 1
      pos 2162
    doc 9
      freq 4
      pos 122
      pos 384
      pos 1103
      pos 1807
    doc 10
      freq 1
      pos 13468
    doc 11
      freq 1
      pos 10629
    doc 12
      freq 1
      pos 9479
    doc 13
      freq 4
      pos 158
      pos 1076
      pos 1523
      pos 7094
    doc 14
      freq 1
      pos 5560
    doc 15
      freq 2
      pos 3819
      pos 4079
    doc 16
      freq 1
      pos 2690
    doc 17
      freq 6
      pos 923
      pos 1022
      pos 1124
      pos 1198
      pos 2353
      pos 2414
    doc 18
      freq 1
      pos 2202
    skipList 
      level 0
        skipDoc 7
        skipDocFP 2172936
        impacts 
          impact 
            freq 5
            norm 100
        impactsEnd 
        skipDoc 15
        skipDocFP 2173374
        impacts 
          impact 
            freq 4
            norm 95
        impactsEnd 
  term statements
    doc 0
      freq 3
      pos 14383
      pos 17087
      pos 17185
    doc 2
      freq 5
      pos 511
      pos 535
      pos 546
      pos 618
      pos 2260
    doc 17
      freq 1
      pos 1824
  term states
    doc 0
      freq 1
      pos 1639
    doc 3
      freq 1
      pos 3317
    doc 5
      freq 1
      pos 1165
    doc 10
      freq 1
      pos 9232
    doc 14
      freq 1
      pos 1909
    doc 17
      freq 1
      pos 92
  term static
    doc 0
      freq 2
      pos 5220
      pos 11653
    doc 1
      freq 2
      pos 1879
      pos 1896
    doc 9
      freq 1
      pos 24
    doc 10
      freq 1
      pos 2183
    doc 12
      freq 2
      pos 4468
      pos 4479
  term statically
    doc 1
      freq 1
      pos 2973
  term staticin
    doc 0
      freq 1
      pos 5726
  term staticout
    doc 0
      freq 1
      pos 5728
  term station
    doc 0
      freq 1
      pos 16529
    doc 7
      freq 2
      pos 1071
      pos 2645
  term statistical
    doc 13
      freq 1
      pos 5075
  term statistics
    doc 6
      freq 5
      pos 691
      pos 2473
      pos 2506
      pos 2532
      pos 2598
    doc 13
      freq 1
      pos 3122
  term status
    doc 0
      freq 260
      pos 28
      pos 70
      pos 1412
      pos 1435
      pos 1499
      pos 1584
      pos 1619
      pos 1636
      pos 1658
      pos 1706
      pos 1751
      pos 1802
      pos 1829
      pos 1855
      pos 1886
      pos 1912
      pos 1952
      pos 1973
      pos 1999
      pos 2026
      pos 2061
      pos 2295
      pos 2338
      pos 2391
      pos 2473
      pos 2550
      pos 2619
      pos 2671
      pos 2729
      pos 2776
      pos 2814
      pos 2862
      pos 2955
      pos 2981
      pos 3042
      pos 3141
      pos 3182
      pos 3238
      pos 3359
      pos 3413
      pos 3473
      pos 3528
      pos 3596
      pos 3701
      pos 3724
      pos 3778
      pos 3887
      pos 3930
      pos 3960
      pos 4022
      pos 4104
      pos 4213
      pos 4236
      pos 4290
      pos 4387
      pos 4463
      pos 4484
      pos 4531
      pos 4564
      pos 4590
      pos 4617
      pos 4657
      pos 4677
      pos 4741
      pos 4761
      pos 4830
      pos 4870
      pos 4969
      pos 5034
      pos 5146
      pos 5175
      pos 5205
      pos 5246
      pos 5415
      pos 5438
      pos 5518
      pos 5597
      pos 5630
      pos 5652
      pos 5736
      pos 5795
      pos 5832
      pos 5909
      pos 5960
      pos 6025
      pos 6085
      pos 6139
      pos 6195
      pos 6219
      pos 6281
      pos 6304
      pos 6387
      pos 6407
      pos 6448
      pos 6474
      pos 6508
      pos 6616
      pos 6726
      pos 6787
      pos 6846
      pos 6940
      pos 6987
      pos 7027
      pos 7105
      pos 7162
      pos 7210
      pos 7231
      pos 7292
      pos 7319
      pos 7392
      pos 7425
      pos 7450
      pos 7477
      pos 7519
      pos 7550
      pos 7577
      pos 7621
      pos 7660
      pos 7688
      pos 7721
      pos 7757
      pos 7778
      pos 7849
      pos 7904
      pos 7935
      pos 7972
      pos 8013
      pos 8052
      pos 8093
      pos 8147
      pos 8184
      pos 8218
      pos 8277
      pos 8306
      pos 8371
      pos 8399
      pos 8446
      pos 8514
      pos 8572
      pos 8630
      pos 8687
      pos 8732
      pos 8774
      pos 8833
      pos 8854
      pos 8919
      pos 8981
      pos 9012
      pos 9057
      pos 9102
      pos 9126
      pos 9152
      pos 9182
      pos 9256
      pos 9296
      pos 9326
      pos 9405
      pos 9453
      pos 9504
      pos 9536
      pos 9604
      pos 9636
      pos 9689
      pos 9718
      pos 9759
      pos 9829
      pos 9861
      pos 9921
      pos 9979
      pos 10003
      pos 10079
      pos 10112
      pos 10161
      pos 10202
      pos 10247
      pos 10474
      pos 10511
      pos 10545
      pos 10621
      pos 10719
      pos 10819
      pos 10893
      pos 10926
      pos 11077
      pos 11110
      pos 11155
      pos 11253
      pos 11284
      pos 11318
      pos 11357
      pos 11409
      pos 11460
      pos 11504
      pos 11537
      pos 11567
      pos 11601
      pos 11677
      pos 11717
      pos 11736
      pos 11805
      pos 11826
      pos 11850
      pos 11870
      pos 11904
      pos 11928
      pos 11950
      pos 11969
      pos 12042
      pos 12075
      pos 12132
      pos 12169
      pos 12201
      pos 12223
      pos 12242
      pos 12265
      pos 12319
      pos 12342
      pos 12366
      pos 12391
      pos 12419
      pos 12444
      pos 12482
      pos 12508
      pos 12538
      pos 12582
      pos 12609
      pos 12657
      pos 12678
      pos 12733
      pos 12754
      pos 12792
      pos 12831
      pos 12924
      pos 13005
      pos 13078
      pos 13192
      pos 13281
      pos 13333
      pos 13412
      pos 13498
      pos 13597
      pos 13687
      pos 13790
      pos 13864
      pos 13949
      pos 14077
      pos 14205
      pos 14256
      pos 14387
      pos 14552
      pos 14763
      pos 15459
      pos 15527
      pos 15573
      pos 15608
      pos 15654
      pos 15678
      pos 15706
      pos 15748
      pos 15778
    doc 1
      freq 73
      pos 45
      pos 87
      pos 291
      pos 303
      pos 307
      pos 373
      pos 812
      pos 2296
      pos 2345
      pos 2368
      pos 2381
      pos 2718
      pos 2829
      pos 4183
      pos 4286
      pos 4546
      pos 4806
      pos 4884
      pos 4887
      pos 4912
      pos 4930
      pos 4962
      pos 4973
      pos 4999
      pos 5027
      pos 5037
      pos 5044
      pos 5061
      pos 5103
      pos 5106
      pos 5109
      pos 5133
      pos 5145
      pos 5211
      pos 5276
      pos 5279
      pos 5304
      pos 5306
      pos 5313
      pos 5318
      pos 5386
      pos 5404
      pos 5411
      pos 5471
      pos 5579
      pos 5605
      pos 5626
      pos 5639
      pos 5662
      pos 5749
      pos 5752
      pos 5757
      pos 5788
      pos 5800
      pos 5814
      pos 5820
      pos 5847
      pos 5874
      pos 5897
      pos 5918
      pos 5931
      pos 5937
      pos 5943
      pos 5959
      pos 6346
      pos 6899
      pos 6933
      pos 7782
      pos 7795
      pos 7803
      pos 7812
      pos 7860
      pos 7879
    doc 2
      freq 3
      pos 22
      pos 1818
      pos 5390
    doc 3
      freq 7
      pos 39
      pos 81
      pos 1547
      pos 1554
      pos 1562
      pos 1808
      pos 1888
    doc 4
      freq 3
      pos 41
      pos 83
      pos 4830
    doc 5
      freq 2
      pos 25
      pos 67
    doc 6
      freq 1
      pos 25
    doc 7
      freq 6
      pos 36
      pos 270
      pos 281
      pos 483
      pos 1146
      pos 1711
    doc 8
      freq 7
      pos 29
      pos 156
      pos 1510
      pos 1520
      pos 1529
      pos 1539
      pos 1575
    doc 9
      freq 2
      pos 27
      pos 69
    doc 10
      freq 2
      pos 30
      pos 72
    doc 11
      freq 1
      pos 38
    doc 12
      freq 1
      pos 28
    doc 13
      freq 1
      pos 37
    doc 14
      freq 1
      pos 23
    doc 15
      freq 2
      pos 36
      pos 3690
    doc 16
      freq 2
      pos 26
      pos 68
    doc 17
      freq 7
      pos 23
      pos 65
      pos 1427
      pos 1434
      pos 1513
      pos 1581
      pos 1624
    doc 18
      freq 2
      pos 32
      pos 74
    skipList 
      level 0
        skipDoc 7
        skipDocFP 2175498
        impacts 
          impact 
            freq 6
            norm 100
          impact 
            freq 7
            norm 107
          impact 
            freq 73
            norm 113
          impact 
            freq 260
            norm 120
        impactsEnd 
        skipDoc 15
        skipDocFP 2181067
        impacts 
          impact 
            freq 2
            norm 95
          impact 
            freq 7
            norm 97
        impactsEnd 
  term std
    doc 0
      freq 8
      pos 63
      pos 283
      pos 288
      pos 294
      pos 17033
      pos 17054
      pos 17072
      pos 17090
    doc 1
      freq 1
      pos 80
    doc 2
      freq 3
      pos 2551
      pos 2617
      pos 3424
    doc 3
      freq 2
      pos 74
      pos 4468
    doc 4
      freq 3
      pos 76
      pos 5220
      pos 5260
    doc 5
      freq 1
      pos 60
    doc 6
      freq 1
      pos 3080
    doc 9
      freq 1
      pos 62
    doc 10
      freq 1
      pos 65
    doc 11
      freq 1
      pos 9689
    doc 12
      freq 1
      pos 7005
    doc 14
      freq 2
      pos 5370
      pos 5384
    doc 16
      freq 1
      pos 61
    doc 17
      freq 1
      pos 58
    doc 18
      freq 1
      pos 67
    skipList 
      level 0
        skipDoc 9
        skipDocFP 2182267
        impacts 
          impact 
            freq 1
            norm 95
          impact 
            freq 2
            norm 107
          impact 
            freq 3
            norm 108
          impact 
            freq 8
            norm 120
        impactsEnd 
  term steering
    doc 2
      freq 2
      pos 351
      pos 424
  term steffen
    doc 5
      freq 1
      pos 4398
  term steffen.fries
    doc 5
      freq 1
      pos 4410
  term stein
    doc 1
      freq 1
      pos 9002
    doc 8
      freq 2
      pos 1892
      pos 2037
  term step
    doc 7
      freq 1
      pos 1465
    doc 10
      freq 9
      pos 2339
      pos 2520
      pos 2660
      pos 3140
      pos 3298
      pos 3925
      pos 4151
      pos 4190
      pos 4244
    doc 14
      freq 19
      pos 648
      pos 742
      pos 773
      pos 804
      pos 872
      pos 947
      pos 997
      pos 1063
      pos 1116
      pos 1190
      pos 1231
      pos 1241
      pos 1282
      pos 1328
      pos 1433
      pos 1464
      pos 1609
      pos 1649
      pos 1715
  term stephen
    doc 4
      freq 1
      pos 6058
  term stephen.vogelsang
    doc 1
      freq 1
      pos 9264
    doc 3
      freq 1
      pos 4794
  term steps
    doc 0
      freq 1
      pos 2153
    doc 7
      freq 2
      pos 138
      pos 1427
    doc 10
      freq 2
      pos 2327
      pos 3919
    doc 14
      freq 1
      pos 1338
  term steve
    doc 1
      freq 1
      pos 9250
    doc 3
      freq 1
      pos 4780
    doc 11
      freq 1
      pos 9592
  term stewart
    doc 0
      freq 1
      pos 17181
  term stfqcniv
    doc 11
      freq 1
      pos 10377
  term stig
    doc 15
      freq 1
      pos 4036
  term still
    doc 0
      freq 3
      pos 2044
      pos 2079
      pos 12022
    doc 1
      freq 1
      pos 7485
    doc 7
      freq 2
      pos 1390
      pos 1694
    doc 8
      freq 1
      pos 296
    doc 10
      freq 1
      pos 628
    doc 11
      freq 1
      pos 8596
    doc 12
      freq 4
      pos 1376
      pos 4354
      pos 5145
      pos 8675
    doc 13
      freq 1
      pos 4140
    doc 15
      freq 6
      pos 1716
      pos 1978
      pos 2722
      pos 3358
      pos 3367
      pos 3662
    doc 16
      freq 1
      pos 1366
    doc 18
      freq 3
      pos 586
      pos 1267
      pos 1928
    skipList 
      level 0
        skipDoc 13
        skipDocFP 2184807
        impacts 
          impact 
            freq 1
            norm 97
          impact 
            freq 2
            norm 100
          impact 
            freq 4
            norm 113
        impactsEnd 
  term stimulat
    doc 11
      freq 1
      pos 9394
  term stipulates
    doc 10
      freq 1
      pos 457
  term stockholm
    doc 12
      freq 1
      pos 9449
    doc 18
      freq 1
      pos 2180
  term stop
    doc 0
      freq 1
      pos 16336
    doc 18
      freq 1
      pos 129
  term stops
    doc 14
      freq 1
      pos 644
  term storag
    doc 9
      freq 1
      pos 928
    doc 13
      freq 2
      pos 2224
      pos 2648
    doc 16
      freq 1
      pos 447
  term store
    doc 0
      freq 3
      pos 230
      pos 2876
      pos 2909
    doc 12
      freq 1
      pos 5156
    doc 15
      freq 1
      pos 998
    doc 16
      freq 4
      pos 341
      pos 380
      pos 2099
      pos 2106
  term stored
    doc 0
      freq 4
      pos 906
      pos 11748
      pos 12087
      pos 12939
    doc 5
      freq 1
      pos 2318
    doc 12
      freq 1
      pos 6617
    doc 13
      freq 5
      pos 2496
      pos 4040
      pos 4727
      pos 4966
      pos 4974
  term storing
    doc 12
      freq 1
      pos 7561
    doc 18
      freq 1
      pos 1668
  term straightforward
    doc 10
      freq 1
      pos 10422
    doc 12
      freq 2
      pos 6277
      pos 6462
    doc 15
      freq 2
      pos 580
      pos 3441
  term strategic
    doc 6
      freq 1
      pos 2729
  term strategies
    doc 10
      freq 3
      pos 303
      pos 11007
      pos 11233
    doc 12
      freq 1
      pos 3149
    doc 15
      freq 1
      pos 1769
  term strategy
    doc 6
      freq 1
      pos 2616
    doc 7
      freq 1
      pos 2470
    doc 15
      freq 2
      pos 171
      pos 2854
  term stratton
    doc 1
      freq 1
      pos 9186
  term strauf
    doc 15
      freq 3
      pos 18
      pos 4047
      pos 4060
  term stream
    doc 4
      freq 1
      pos 1859
    doc 5
      freq 5
      pos 20
      pos 90
      pos 1454
      pos 4196
      pos 4221
    doc 6
      freq 24
      pos 566
      pos 638
      pos 675
      pos 824
      pos 898
      pos 974
      pos 1059
      pos 1178
      pos 1219
      pos 1242
      pos 1377
      pos 1386
      pos 1439
      pos 1473
      pos 1512
      pos 1593
      pos 1637
      pos 1708
      pos 2095
      pos 2136
      pos 2295
      pos 2404
      pos 2833
      pos 2841
    doc 11
      freq 3
      pos 3871
      pos 4394
      pos 4429
  term streaming
    doc 6
      freq 13
      pos 207
      pos 268
      pos 330
      pos 443
      pos 553
      pos 582
      pos 813
      pos 943
      pos 1019
      pos 1054
      pos 2067
      pos 2076
      pos 2748
    doc 13
      freq 5
      pos 919
      pos 2675
      pos 2879
      pos 2919
      pos 3220
  term streams
    doc 6
      freq 4
      pos 597
      pos 841
      pos 863
      pos 1207
    doc 13
      freq 2
      pos 3114
      pos 3164
  term street
    doc 1
      freq 1
      pos 9547
    doc 3
      freq 1
      pos 5912
    doc 17
      freq 1
      pos 2373
  term strength
    doc 2
      freq 1
      pos 2379
  term stress
    doc 0
      freq 1
      pos 16310
    doc 11
      freq 3
      pos 629
      pos 636
      pos 9367
  term stressful
    doc 0
      freq 1
      pos 16089
  term strict
    doc 3
      freq 4
      pos 2919
      pos 2976
      pos 3003
      pos 3503
    doc 10
      freq 2
      pos 1517
      pos 12395
    doc 11
      freq 1
      pos 9800
    doc 12
      freq 1
      pos 8533
    doc 18
      freq 1
      pos 1213
  term strictly
    doc 3
      freq 1
      pos 651
    doc 10
      freq 1
      pos 7713
  term string
    doc 0
      freq 13
      pos 1428
      pos 1493
      pos 1578
      pos 1966
      pos 1989
      pos 3221
      pos 4603
      pos 6710
      pos 6769
      pos 12120
      pos 12257
      pos 12371
      pos 12600
    doc 1
      freq 7
      pos 3771
      pos 4479
      pos 4496
      pos 6216
      pos 6226
      pos 6235
      pos 6257
    doc 5
      freq 1
      pos 2693
    doc 8
      freq 1
      pos 1035
    doc 10
      freq 27
      pos 275
      pos 4211
      pos 4233
      pos 4862
      pos 4894
      pos 5050
      pos 5117
      pos 5202
      pos 5313
      pos 5325
      pos 5408
      pos 5515
      pos 6457
      pos 6579
      pos 6745
      pos 6759
      pos 7174
      pos 7195
      pos 7207
      pos 7297
      pos 8212
      pos 9431
      pos 11884
      pos 12228
      pos 12242
      pos 12255
      pos 12272
    doc 11
      freq 11
      pos 285
      pos 947
      pos 1058
      pos 1524
      pos 1673
      pos 1703
      pos 1741
      pos 1795
      pos 1810
      pos 3941
      pos 5079
    doc 14
      freq 1
      pos 2015
    doc 16
      freq 4
      pos 567
      pos 657
      pos 706
      pos 831
    doc 17
      freq 2
      pos 1208
      pos 1253
    skipList 
      level 0
        skipDoc 16
        skipDocFP 2189277
        impacts 
          impact 
            freq 1
            norm 97
          impact 
            freq 4
            norm 99
          impact 
            freq 7
            norm 113
          impact 
            freq 11
            norm 114
          impact 
            freq 27
            norm 116
        impactsEnd 
  term strings
    doc 1
      freq 1
      pos 3758
    doc 8
      freq 1
      pos 1525
    doc 10
      freq 1
      pos 5989
    doc 11
      freq 6
      pos 120
      pos 988
      pos 1038
      pos 1091
      pos 1103
      pos 1124
  term strip
    doc 3
      freq 1
      pos 2718
    doc 10
      freq 2
      pos 5036
      pos 9885
    doc 16
      freq 1
      pos 2134
  term stripped
    doc 3
      freq 4
      pos 2147
      pos 2289
      pos 2301
      pos 2522
    doc 16
      freq 1
      pos 2152
  term stripping
    doc 3
      freq 1
      pos 994
    doc 10
      freq 1
      pos 9320
  term strips
    doc 3
      freq 1
      pos 1360
  term strong
    doc 4
      freq 1
      pos 4312
    doc 10
      freq 3
      pos 865
      pos 11156
      pos 12877
    doc 12
      freq 1
      pos 6556
    doc 15
      freq 1
      pos 3604
    doc 17
      freq 2
      pos 1472
      pos 1687
  term stronger
    doc 9
      freq 1
      pos 291
    doc 10
      freq 1
      pos 656
    doc 12
      freq 5
      pos 4456
      pos 4533
      pos 5516
      pos 5595
      pos 5647
    doc 17
      freq 1
      pos 1648
  term strongest
    doc 10
      freq 1
      pos 10023
  term strongly
    doc 10
      freq 1
      pos 10958
    doc 18
      freq 2
      pos 364
      pos 491
  term structur
    doc 0
      freq 3
      pos 262
      pos 1252
      pos 17047
    doc 1
      freq 2
      pos 6011
      pos 9004
    doc 8
      freq 6
      pos 736
      pos 743
      pos 751
      pos 758
      pos 1894
      pos 2022
    doc 10
      freq 1
      pos 12433
    doc 11
      freq 1
      pos 9840
    doc 16
      freq 1
      pos 1724
  term structured
    doc 1
      freq 2
      pos 2955
      pos 3149
    doc 13
      freq 3
      pos 597
      pos 1935
      pos 5396
  term structures
    doc 1
      freq 1
      pos 724
    doc 12
      freq 1
      pos 6664
  term structuring
    doc 13
      freq 1
      pos 659
  term stub
    doc 12
      freq 2
      pos 4179
      pos 8013
  term study
    doc 10
      freq 1
      pos 5916
  term style
    doc 0
      freq 3
      pos 1863
      pos 5150
      pos 5179
    doc 11
      freq 2
      pos 7029
      pos 7094
    doc 13
      freq 1
      pos 726
  term sub
    doc 0
      freq 6
      pos 1623
      pos 1710
      pos 2003
      pos 3628
      pos 4144
      pos 10985
    doc 1
      freq 21
      pos 314
      pos 2500
      pos 2592
      pos 2624
      pos 2765
      pos 2789
      pos 3793
      pos 3800
      pos 3811
      pos 4042
      pos 4067
      pos 5351
      pos 5523
      pos 5658
      pos 5969
      pos 6066
      pos 6079
      pos 6137
      pos 6217
      pos 7178
      pos 7313
    doc 2
      freq 1
      pos 1885
    doc 3
      freq 5
      pos 215
      pos 1933
      pos 1937
      pos 1996
      pos 2017
    doc 4
      freq 1
      pos 5570
    doc 8
      freq 10
      pos 133
      pos 808
      pos 822
      pos 831
      pos 842
      pos 862
      pos 882
      pos 1000
      pos 1107
      pos 1111
    doc 10
      freq 8
      pos 5801
      pos 5832
      pos 11455
      pos 11515
      pos 11618
      pos 11713
      pos 11814
      pos 11908
    doc 12
      freq 2
      pos 2334
      pos 2398
    skipList 
      level 0
        skipDoc 12
        skipDocFP 2193172
        impacts 
          impact 
            freq 10
            norm 97
          impact 
            freq 21
            norm 113
        impactsEnd 
  term subdivided
    doc 8
      freq 1
      pos 229
  term subdomain
    doc 15
      freq 1
      pos 1368
  term subdomains
    doc 0
      freq 1
      pos 10391
  term subidentifiers
    doc 0
      freq 3
      pos 3650
      pos 4166
      pos 11008
  term subject
    doc 0
      freq 3
      pos 16305
      pos 16388
      pos 17235
    doc 1
      freq 1
      pos 9616
    doc 2
      freq 1
      pos 6413
    doc 3
      freq 2
      pos 4073
      pos 5965
    doc 4
      freq 6
      pos 377
      pos 4103
      pos 4135
      pos 4183
      pos 4326
      pos 6120
    doc 5
      freq 2
      pos 3174
      pos 4450
    doc 6
      freq 2
      pos 679
      pos 3245
    doc 7
      freq 1
      pos 2955
    doc 8
      freq 1
      pos 2172
    doc 9
      freq 1
      pos 1817
    doc 10
      freq 8
      pos 1599
      pos 5913
      pos 6128
      pos 7762
      pos 10403
      pos 10561
      pos 11316
      pos 13478
    doc 11
      freq 4
      pos 1076
      pos 1083
      pos 1224
      pos 10639
    doc 12
      freq 1
      pos 9489
    doc 13
      freq 1
      pos 7104
    doc 14
      freq 2
      pos 2125
      pos 5570
    doc 15
      freq 1
      pos 4089
    doc 16
      freq 4
      pos 1895
      pos 2011
      pos 2379
      pos 2700
    doc 17
      freq 2
      pos 185
      pos 2424
    doc 18
      freq 1
      pos 2212
    skipList 
      level 0
        skipDoc 7
        skipDocFP 2194669
        impacts 
          impact 
            freq 1
            norm 100
          impact 
            freq 2
            norm 101
          impact 
            freq 6
            norm 108
        impactsEnd 
        skipDoc 15
        skipDocFP 2195124
        impacts 
          impact 
            freq 1
            norm 95
          impact 
            freq 2
            norm 107
          impact 
            freq 4
            norm 114
          impact 
            freq 8
            norm 116
        impactsEnd 
  term subjectaltnam
    doc 10
      freq 1
      pos 6131
  term subjecting
    doc 0
      freq 1
      pos 16086
  term subjects
    doc 2
      freq 1
      pos 1744
    doc 10
      freq 2
      pos 10442
      pos 10448
  term sublayer
    doc 2
      freq 3
      pos 271
      pos 3258
      pos 4000
  term submission
    doc 12
      freq 1
      pos 2193
    doc 16
      freq 1
      pos 330
  term submit
    doc 2
      freq 1
      pos 571
  term submitted
    doc 2
      freq 3
      pos 1509
      pos 1834
      pos 4560
  term subnet
    doc 4
      freq 1
      pos 2528
    doc 12
      freq 2
      pos 5307
      pos 5901
  term subnetwork
    doc 0
      freq 9
      pos 10303
      pos 10312
      pos 10416
      pos 10455
      pos 10939
      pos 11125
      pos 16223
      pos 16329
      pos 16340
  term subnetworks
    doc 0
      freq 1
      pos 10904
  term suboptimal
    doc 12
      freq 1
      pos 2434
  term suboption
    doc 9
      freq 1
      pos 962
  term subordinat
    doc 10
      freq 2
      pos 10473
      pos 10542
  term subordination
    doc 10
      freq 2
      pos 297
      pos 10367
  term subpart
    doc 13
      freq 2
      pos 5842
      pos 5882
  term subparts
    doc 13
      freq 1
      pos 6231
  term subscrib
    doc 13
      freq 3
      pos 2240
      pos 3535
      pos 6068
  term subscribed
    doc 2
      freq 1
      pos 1021
  term subscribers
    doc 10
      freq 1
      pos 795
    doc 13
      freq 2
      pos 1841
      pos 6162
  term subscription
    doc 10
      freq 1
      pos 808
    doc 13
      freq 1
      pos 5998
  term subscriptions
    doc 13
      freq 1
      pos 1015
  term subsections
    doc 12
      freq 1
      pos 8627
    doc 15
      freq 1
      pos 848
  term subsequent
    doc 1
      freq 1
      pos 5955
    doc 2
      freq 2
      pos 4577
      pos 5102
    doc 6
      freq 1
      pos 2467
    doc 10
      freq 1
      pos 9018
    doc 11
      freq 4
      pos 3601
      pos 8707
      pos 8788
      pos 8893
    doc 13
      freq 2
      pos 836
      pos 3028
    doc 15
      freq 1
      pos 1471
    doc 16
      freq 2
      pos 329
      pos 672
    skipList 
      level 0
        skipDoc 16
        skipDocFP 2198173
        impacts 
          impact 
            freq 2
            norm 99
          impact 
            freq 4
            norm 114
        impactsEnd 
  term subsequently
    doc 2
      freq 3
      pos 5480
      pos 5954
      pos 6195
    doc 5
      freq 1
      pos 2878
    doc 9
      freq 2
      pos 107
      pos 777
    doc 13
      freq 1
      pos 3341
    doc 15
      freq 1
      pos 334
  term subset
    doc 0
      freq 1
      pos 3569
    doc 5
      freq 1
      pos 3634
    doc 12
      freq 1
      pos 4002
    doc 13
      freq 5
      pos 686
      pos 4393
      pos 4457
      pos 5851
      pos 5891
    doc 15
      freq 1
      pos 557
  term subsets
    doc 4
      freq 2
      pos 2681
      pos 3451
  term substantial
    doc 2
      freq 1
      pos 4970
  term substantially
    doc 2
      freq 1
      pos 636
  term substitut
    doc 18
      freq 1
      pos 1620
  term substitutes
    doc 10
      freq 1
      pos 10797
  term subsystem
    doc 0
      freq 2
      pos 6163
      pos 9353
  term subtleties
    doc 15
      freq 1
      pos 3043
  term subtlety
    doc 15
      freq 1
      pos 1401
  term subtract
    doc 18
      freq 1
      pos 1357
  term subverts
    doc 18
      freq 1
      pos 295
  term succeed
    doc 11
      freq 3
      pos 8680
      pos 8785
      pos 8890
  term succeeds
    doc 0
      freq 1
      pos 5344
  term success
    doc 18
      freq 1
      pos 1785
  term successful
    doc 2
      freq 1
      pos 4342
    doc 5
      freq 1
      pos 3108
    doc 16
      freq 1
      pos 1926
  term successfully
    doc 2
      freq 1
      pos 787
  term successiv
    doc 0
      freq 1
      pos 4838
  term successor
    doc 5
      freq 2
      pos 3801
      pos 4017
    doc 10
      freq 1
      pos 11338
    doc 14
      freq 34
      pos 22
      pos 81
      pos 147
      pos 165
      pos 221
      pos 403
      pos 442
      pos 463
      pos 473
      pos 564
      pos 599
      pos 613
      pos 848
      pos 906
      pos 1225
      pos 1554
      pos 1562
      pos 1875
      pos 2165
      pos 2556
      pos 2910
      pos 3263
      pos 3547
      pos 3845
      pos 4141
      pos 4227
      pos 4292
      pos 4414
      pos 4508
      pos 4590
      pos 4968
      pos 5196
      pos 5462
      pos 5555
  term successors
    doc 14
      freq 8
      pos 243
      pos 259
      pos 1320
      pos 2398
      pos 2793
      pos 4148
      pos 5130
      pos 5282
  term such
    doc 0
      freq 16
      pos 674
      pos 700
      pos 2130
      pos 4923
      pos 6666
      pos 7988
      pos 8944
      pos 14352
      pos 14788
      pos 15884
      pos 16115
      pos 16175
      pos 16417
      pos 17378
      pos 17400
      pos 17458
    doc 1
      freq 18
      pos 109
      pos 2778
      pos 2827
      pos 3233
      pos 3342
      pos 4417
      pos 4486
      pos 4497
      pos 4747
      pos 5592
      pos 6407
      pos 6567
      pos 6607
      pos 7273
      pos 8084
      pos 9759
      pos 9781
      pos 9839
    doc 2
      freq 9
      pos 1519
      pos 2154
      pos 2206
      pos 4884
      pos 4933
      pos 6235
      pos 6556
      pos 6578
      pos 6636
    doc 3
      freq 6
      pos 399
      pos 990
      pos 1754
      pos 6108
      pos 6130
      pos 6188
    doc 4
      freq 13
      pos 370
      pos 496
      pos 700
      pos 1151
      pos 1554
      pos 2467
      pos 2544
      pos 3396
      pos 4349
      pos 4708
      pos 6263
      pos 6285
      pos 6343
    doc 5
      freq 7
      pos 2782
      pos 2962
      pos 3016
      pos 3498
      pos 4593
      pos 4615
      pos 4673
    doc 6
      freq 19
      pos 128
      pos 205
      pos 341
      pos 356
      pos 421
      pos 445
      pos 555
      pos 760
      pos 998
      pos 1056
      pos 2102
      pos 2261
      pos 2501
      pos 2505
      pos 2660
      pos 2829
      pos 3393
      pos 3415
      pos 3473
    doc 7
      freq 10
      pos 179
      pos 185
      pos 254
      pos 282
      pos 1193
      pos 1207
      pos 1358
      pos 3098
      pos 3120
      pos 3178
    doc 8
      freq 4
      pos 1699
      pos 2315
      pos 2337
      pos 2395
    doc 9
      freq 5
      pos 952
      pos 1036
      pos 1960
      pos 1982
      pos 2040
    doc 10
      freq 21
      pos 451
      pos 1279
      pos 1717
      pos 2948
      pos 4371
      pos 5609
      pos 9025
      pos 9036
      pos 9364
      pos 9603
      pos 9776
      pos 9826
      pos 10081
      pos 10679
      pos 10978
      pos 11087
      pos 11130
      pos 11159
      pos 13621
      pos 13643
      pos 13701
    doc 11
      freq 8
      pos 4397
      pos 4601
      pos 5124
      pos 8448
      pos 9376
      pos 10782
      pos 10804
      pos 10862
    doc 12
      freq 18
      pos 1708
      pos 1887
      pos 5111
      pos 5245
      pos 5355
      pos 5397
      pos 5536
      pos 5987
      pos 6271
      pos 6483
      pos 6600
      pos 6668
      pos 8338
      pos 8814
      pos 9398
      pos 9632
      pos 9654
      pos 9712
    doc 13
      freq 23
      pos 407
      pos 455
      pos 667
      pos 822
      pos 1124
      pos 1933
      pos 2057
      pos 2461
      pos 2593
      pos 2665
      pos 2805
      pos 2826
      pos 2902
      pos 3039
      pos 3066
      pos 3105
      pos 3291
      pos 4869
      pos 5143
      pos 6126
      pos 7247
      pos 7269
      pos 7327
    doc 14
      freq 6
      pos 447
      pos 2119
      pos 2290
      pos 5713
      pos 5735
      pos 5793
    doc 15
      freq 25
      pos 86
      pos 177
      pos 400
      pos 415
      pos 452
      pos 614
      pos 674
      pos 937
      pos 1040
      pos 1124
      pos 1320
      pos 1416
      pos 1581
      pos 2058
      pos 2137
      pos 2242
      pos 2668
      pos 2815
      pos 2828
      pos 3104
      pos 3203
      pos 3715
      pos 4232
      pos 4254
      pos 4312
    doc 16
      freq 5
      pos 484
      pos 1055
      pos 2843
      pos 2865
      pos 2923
    doc 17
      freq 6
      pos 1457
      pos 1490
      pos 1836
      pos 2567
      pos 2589
      pos 2647
    doc 18
      freq 4
      pos 1245
      pos 2355
      pos 2377
      pos 2435
    skipList 
      level 0
        skipDoc 7
        skipDocFP 2201140
        impacts 
          impact 
            freq 10
            norm 100
          impact 
            freq 19
            norm 101
        impactsEnd 
        skipDoc 15
        skipDocFP 2202787
        impacts 
          impact 
            freq 5
            norm 95
          impact 
            freq 25
            norm 104
        impactsEnd 
  term suffic
    doc 10
      freq 1
      pos 5723
    doc 12
      freq 1
      pos 8828
  term sufficient
    doc 1
      freq 1
      pos 7629
    doc 2
      freq 3
      pos 4640
      pos 4809
      pos 6128
    doc 5
      freq 1
      pos 2089
    doc 9
      freq 2
      pos 810
      pos 1075
    doc 10
      freq 1
      pos 8248
    doc 12
      freq 3
      pos 4707
      pos 5497
      pos 6424
    doc 13
      freq 3
      pos 438
      pos 4088
      pos 4363
    doc 15
      freq 2
      pos 2319
      pos 3388
    doc 18
      freq 1
      pos 1601
    skipList 
      level 0
        skipDoc 15
        skipDocFP 2205458
        impacts 
          impact 
            freq 2
            norm 95
          impact 
            freq 3
            norm 108
        impactsEnd 
  term sufficiently
    doc 7
      freq 1
      pos 1242
    doc 9
      freq 1
      pos 466
    doc 12
      freq 1
      pos 2101
  term suffix
    doc 0
      freq 1
      pos 10396
    doc 12
      freq 1
      pos 1540
  term sugarman
    doc 11
      freq 1
      pos 9453
  term suggested
    doc 0
      freq 1
      pos 2631
    doc 1
      freq 2
      pos 7774
      pos 7824
    doc 7
      freq 2
      pos 230
      pos 1143
  term suggestions
    doc 0
      freq 1
      pos 48
    doc 1
      freq 1
      pos 65
    doc 3
      freq 1
      pos 59
    doc 4
      freq 1
      pos 61
    doc 5
      freq 1
      pos 45
    doc 6
      freq 1
      pos 662
    doc 8
      freq 1
      pos 49
    doc 9
      freq 1
      pos 47
    doc 10
      freq 1
      pos 50
    doc 14
      freq 1
      pos 49
    doc 16
      freq 1
      pos 46
    doc 17
      freq 1
      pos 43
    doc 18
      freq 1
      pos 52
    skipList 
      level 0
        skipDoc 9
        skipDocFP 2206608
        impacts 
          impact 
            freq 1
            norm 95
        impactsEnd 
  term suitabl
    doc 2
      freq 1
      pos 578
    doc 13
      freq 3
      pos 1006
      pos 2632
      pos 6308
  term suite
    doc 1
      freq 2
      pos 9514
      pos 9581
    doc 3
      freq 1
      pos 5879
    doc 6
      freq 1
      pos 3206
    doc 8
      freq 1
      pos 2138
    doc 10
      freq 1
      pos 13412
  term suited
    doc 13
      freq 1
      pos 3702
  term sum
    doc 4
      freq 1
      pos 1268
    doc 6
      freq 1
      pos 1735
    doc 14
      freq 1
      pos 2369
  term summarized
    doc 0
      freq 1
      pos 4081
    doc 5
      freq 1
      pos 2260
  term summarizes
    doc 12
      freq 1
      pos 633
  term summary
    doc 0
      freq 28
      pos 531
      pos 892
      pos 3488
      pos 3492
      pos 3499
      pos 3535
      pos 3541
      pos 3553
      pos 3572
      pos 3575
      pos 3604
      pos 3711
      pos 3733
      pos 3789
      pos 3895
      pos 3939
      pos 3970
      pos 4052
      pos 4088
      pos 4113
      pos 4223
      pos 4245
      pos 4301
      pos 4395
      pos 11695
      pos 11743
      pos 14461
      pos 14627
    doc 5
      freq 1
      pos 2834
    doc 6
      freq 1
      pos 2686
    doc 12
      freq 3
      pos 80
      pos 130
      pos 526
    doc 13
      freq 1
      pos 1315
    doc 15
      freq 2
      pos 284
      pos 3226
  term sun4
    doc 11
      freq 1
      pos 10044
  term sundar
    doc 0
      freq 1
      pos 15958
  term sunil
    doc 3
      freq 2
      pos 4973
      pos 4985
  term sunith
    doc 11
      freq 1
      pos 9477
  term sunnyval
    doc 1
      freq 2
      pos 9360
      pos 9374
    doc 3
      freq 1
      pos 4864
    doc 4
      freq 1
      pos 6082
  term supdup
    doc 7
      freq 2
      pos 1863
      pos 1868
  term supplants
    doc 10
      freq 1
      pos 3411
  term supplement
    doc 2
      freq 1
      pos 2658
  term supplemental
    doc 6
      freq 1
      pos 2596
  term supplied
    doc 9
      freq 1
      pos 981
    doc 10
      freq 3
      pos 6011
      pos 6038
      pos 6177
  term supplies
    doc 15
      freq 1
      pos 2055
  term supply
    doc 10
      freq 1
      pos 10548
    doc 14
      freq 1
      pos 2752
  term supplying
    doc 9
      freq 1
      pos 1639
    doc 15
      freq 1
      pos 1164
  term support
    doc 0
      freq 30
      pos 1193
      pos 3897
      pos 4397
      pos 5693
      pos 6120
      pos 10128
      pos 11427
      pos 14396
      pos 14458
      pos 14466
      pos 14482
      pos 14490
      pos 14518
      pos 14526
      pos 14562
      pos 14624
      pos 14632
      pos 14648
      pos 14656
      pos 14684
      pos 14692
      pos 14708
      pos 14716
      pos 14732
      pos 14740
      pos 14772
      pos 15894
      pos 16140
      pos 16737
      pos 17539
    doc 1
      freq 12
      pos 603
      pos 680
      pos 1008
      pos 1894
      pos 1914
      pos 1947
      pos 1962
      pos 2957
      pos 4263
      pos 5797
      pos 7027
      pos 9920
    doc 2
      freq 8
      pos 3060
      pos 3084
      pos 3148
      pos 3723
      pos 3848
      pos 5718
      pos 6081
      pos 6717
    doc 3
      freq 11
      pos 566
      pos 672
      pos 1530
      pos 3862
      pos 3891
      pos 3940
      pos 3943
      pos 5541
      pos 5806
      pos 5854
      pos 6269
    doc 4
      freq 1
      pos 6424
    doc 5
      freq 6
      pos 457
      pos 507
      pos 635
      pos 2772
      pos 2843
      pos 4754
    doc 6
      freq 1
      pos 3554
    doc 7
      freq 5
      pos 2048
      pos 2515
      pos 2665
      pos 2700
      pos 3259
    doc 8
      freq 1
      pos 2476
    doc 9
      freq 3
      pos 1554
      pos 1658
      pos 2121
    doc 10
      freq 12
      pos 539
      pos 551
      pos 885
      pos 4272
      pos 4516
      pos 4630
      pos 5483
      pos 5596
      pos 10869
      pos 11228
      pos 12961
      pos 13782
    doc 11
      freq 4
      pos 3743
      pos 7025
      pos 9058
      pos 10943
    doc 12
      freq 10
      pos 108
      pos 324
      pos 691
      pos 1131
      pos 1823
      pos 3223
      pos 3852
      pos 7248
      pos 7272
      pos 9793
    doc 13
      freq 14
      pos 269
      pos 515
      pos 1771
      pos 1876
      pos 2738
      pos 3314
      pos 3677
      pos 4063
      pos 5052
      pos 5207
      pos 5242
      pos 5336
      pos 5597
      pos 7408
    doc 14
      freq 1
      pos 5874
    doc 15
      freq 3
      pos 77
      pos 2715
      pos 4393
    doc 16
      freq 1
      pos 3004
    doc 17
      freq 3
      pos 359
      pos 1889
      pos 2728
    doc 18
      freq 1
      pos 2516
    skipList 
      level 0
        skipDoc 7
        skipDocFP 2209597
        impacts 
          impact 
            freq 5
            norm 100
          impact 
            freq 6
            norm 104
          impact 
            freq 11
            norm 107
          impact 
            freq 12
            norm 113
          impact 
            freq 30
            norm 120
        impactsEnd 
        skipDoc 15
        skipDocFP 2210912
        impacts 
          impact 
            freq 3
            norm 95
          impact 
            freq 14
            norm 109
        impactsEnd 
  term supported
    doc 0
      freq 15
      pos 805
      pos 1665
      pos 2888
      pos 2965
      pos 9794
      pos 9800
      pos 9807
      pos 9839
      pos 9869
      pos 9925
      pos 12616
      pos 13984
      pos 14097
      pos 14120
      pos 14148
    doc 1
      freq 10
      pos 2188
      pos 2384
      pos 4876
      pos 4937
      pos 4965
      pos 5824
      pos 6624
      pos 6689
      pos 6751
      pos 7715
    doc 2
      freq 1
      pos 3904
    doc 3
      freq 2
      pos 1602
      pos 3913
    doc 5
      freq 1
      pos 3196
    doc 7
      freq 3
      pos 438
      pos 1235
      pos 1255
    doc 10
      freq 2
      pos 4380
      pos 11175
    doc 11
      freq 1
      pos 6668
    doc 13
      freq 2
      pos 738
      pos 2326
    skipList 
      level 0
        skipDoc 11
        skipDocFP 2212583
        impacts 
          impact 
            freq 3
            norm 100
          impact 
            freq 10
            norm 113
          impact 
            freq 15
            norm 120
        impactsEnd 
  term supporting
    doc 1
      freq 1
      pos 5906
    doc 2
      freq 1
      pos 2418
    doc 3
      freq 2
      pos 1345
      pos 5437
    doc 5
      freq 2
      pos 469
      pos 842
    doc 10
      freq 1
      pos 3938
    doc 11
      freq 1
      pos 9053
    doc 13
      freq 1
      pos 2415
    doc 15
      freq 1
      pos 1874
    skipList 
      level 0
        skipDoc 15
        skipDocFP 2213657
        impacts 
          impact 
            freq 2
            norm 104
        impactsEnd 
  term supports
    doc 1
      freq 1
      pos 5636
    doc 3
      freq 1
      pos 1508
    doc 5
      freq 1
      pos 727
    doc 7
      freq 1
      pos 1377
    doc 10
      freq 1
      pos 11221
    doc 12
      freq 1
      pos 3327
    doc 16
      freq 2
      pos 514
      pos 1913
    doc 17
      freq 1
      pos 984
    skipList 
      level 0
        skipDoc 17
        skipDocFP 2214177
        impacts 
          impact 
            freq 1
            norm 98
          impact 
            freq 2
            norm 99
        impactsEnd 
  term suppos
    doc 1
      freq 1
      pos 1190
  term supposed
    doc 4
      freq 1
      pos 5575
    doc 11
      freq 1
      pos 8365
  term suppress
    doc 0
      freq 1
      pos 5800
  term sure
    doc 1
      freq 2
      pos 4710
      pos 8450
    doc 10
      freq 3
      pos 6443
      pos 7047
      pos 8266
    doc 11
      freq 2
      pos 1915
      pos 1959
    doc 16
      freq 1
      pos 1064
    doc 17
      freq 1
      pos 374
  term surfac
    doc 13
      freq 1
      pos 2758
  term surpris
    doc 11
      freq 1
      pos 2432
  term surviv
    doc 0
      freq 27
      pos 2370
      pos 2452
      pos 2513
      pos 2594
      pos 2646
      pos 2696
      pos 2759
      pos 2793
      pos 2841
      pos 2932
      pos 3016
      pos 3159
      pos 3440
      pos 3610
      pos 4126
      pos 4503
      pos 4692
      pos 5459
      pos 6327
      pos 8875
      pos 9477
      pos 9660
      pos 9886
      pos 10023
      pos 10967
      pos 11757
      pos 12096
  term susceptibility
    doc 14
      freq 1
      pos 2732
  term susceptibl
    doc 6
      freq 1
      pos 864
    doc 14
      freq 1
      pos 5331
  term suspicious
    doc 0
      freq 2
      pos 12718
      pos 14347
  term sustain
    doc 2
      freq 1
      pos 4804
  term sutter
    doc 10
      freq 1
      pos 13410
  term suzann
    doc 18
      freq 1
      pos 2023
  term sv2005
    doc 12
      freq 2
      pos 4681
      pos 7860
  term sv5cto05kqpsmtht3dce
    doc 10
      freq 2
      pos 7276
      pos 7366
  term swallow
    doc 3
      freq 1
      pos 4313
    doc 8
      freq 1
      pos 2102
  term swaminath
    doc 0
      freq 1
      pos 15960
  term sweden
    doc 12
      freq 1
      pos 9450
    doc 18
      freq 1
      pos 2184
  term swhbo4qnjliwzetsnka6b
    doc 11
      freq 1
      pos 9911
  term swift
    doc 10
      freq 1
      pos 9551
  term switch
    doc 3
      freq 1
      pos 2400
    doc 6
      freq 5
      pos 1680
      pos 2264
      pos 2517
      pos 2597
      pos 2603
  term switched
    doc 1
      freq 3
      pos 542
      pos 1266
      pos 1948
    doc 3
      freq 5
      pos 363
      pos 380
      pos 1287
      pos 1308
      pos 1623
    doc 6
      freq 2
      pos 323
      pos 1685
    doc 8
      freq 1
      pos 2030
  term switches
    doc 3
      freq 1
      pos 5213
    doc 6
      freq 3
      pos 2514
      pos 2568
      pos 2583
  term switching
    doc 3
      freq 2
      pos 4156
      pos 4395
  term switzerland
    doc 7
      freq 1
      pos 2909
  term sy5trw
    doc 11
      freq 1
      pos 9921
  term symbol
    doc 11
      freq 3
      pos 1082
      pos 1806
      pos 3478
  term symmetric
    doc 5
      freq 2
      pos 775
      pos 3651
  term symmetrically
    doc 5
      freq 1
      pos 819
  term symposium
    doc 5
      freq 1
      pos 4280
  term synchroniz
    doc 13
      freq 1
      pos 3463
  term synchronization
    doc 2
      freq 1
      pos 4904
    doc 5
      freq 16
      pos 130
      pos 286
      pos 491
      pos 1159
      pos 2061
      pos 2130
      pos 2139
      pos 2147
      pos 2196
      pos 2203
      pos 2241
      pos 2253
      pos 2457
      pos 2499
      pos 2511
      pos 4083
    doc 13
      freq 1
      pos 3327
  term synchronized
    doc 5
      freq 1
      pos 1153
    doc 13
      freq 2
      pos 4780
      pos 4808
  term synchronizing
    doc 10
      freq 1
      pos 1719
  term synchronous
    doc 1
      freq 5
      pos 155
      pos 592
      pos 597
      pos 9126
      pos 9143
  term synonymous
    doc 11
      freq 1
      pos 6136
  term syntactic
    doc 11
      freq 1
      pos 1597
  term syntactically
    doc 11
      freq 5
      pos 1294
      pos 2023
      pos 4253
      pos 7580
      pos 7803
    doc 13
      freq 1
      pos 5565
  term syntax
    doc 0
      freq 238
      pos 1176
      pos 1426
      pos 1491
      pos 1576
      pos 1595
      pos 1629
      pos 1645
      pos 1692
      pos 1741
      pos 1792
      pos 1824
      pos 1846
      pos 1875
      pos 1901
      pos 1941
      pos 1964
      pos 1987
      pos 2016
      pos 2051
      pos 2086
      pos 2285
      pos 2320
      pos 2385
      pos 2465
      pos 2528
      pos 2609
      pos 2661
      pos 2711
      pos 2770
      pos 2804
      pos 2852
      pos 2943
      pos 2975
      pos 3034
      pos 3135
      pos 3176
      pos 3232
      pos 3351
      pos 3407
      pos 3467
      pos 3520
      pos 3590
      pos 3695
      pos 3718
      pos 3772
      pos 3881
      pos 3924
      pos 3954
      pos 4002
      pos 4098
      pos 4207
      pos 4230
      pos 4284
      pos 4381
      pos 4455
      pos 4478
      pos 4525
      pos 4558
      pos 4584
      pos 4611
      pos 4649
      pos 4671
      pos 4735
      pos 4755
      pos 4808
      pos 4864
      pos 4963
      pos 5020
      pos 5140
      pos 5169
      pos 5199
      pos 5228
      pos 5407
      pos 5432
      pos 5512
      pos 5579
      pos 5624
      pos 5646
      pos 5720
      pos 5789
      pos 5826
      pos 5903
      pos 5936
      pos 6019
      pos 6079
      pos 6133
      pos 6189
      pos 6213
      pos 6273
      pos 6298
      pos 6381
      pos 6401
      pos 6442
      pos 6468
      pos 6500
      pos 6610
      pos 6720
      pos 6779
      pos 6836
      pos 6930
      pos 6977
      pos 7017
      pos 7095
      pos 7152
      pos 7202
      pos 7225
      pos 7286
      pos 7306
      pos 7378
      pos 7411
      pos 7444
      pos 7471
      pos 7501
      pos 7544
      pos 7571
      pos 7607
      pos 7654
      pos 7670
      pos 7705
      pos 7749
      pos 7772
      pos 7837
      pos 7898
      pos 7929
      pos 7966
      pos 8007
      pos 8037
      pos 8087
      pos 8141
      pos 8178
      pos 8212
      pos 8269
      pos 8300
      pos 8365
      pos 8389
      pos 8426
      pos 8495
      pos 8553
      pos 8610
      pos 8667
      pos 8712
      pos 8757
      pos 8813
      pos 8848
      pos 8911
      pos 8967
      pos 8998
      pos 9051
      pos 9088
      pos 9120
      pos 9146
      pos 9176
      pos 9234
      pos 9290
      pos 9320
      pos 9397
      pos 9447
      pos 9496
      pos 9530
      pos 9584
      pos 9630
      pos 9681
      pos 9712
      pos 9753
      pos 9821
      pos 9855
      pos 9915
      pos 9971
      pos 9997
      pos 10071
      pos 10106
      pos 10155
      pos 10196
      pos 10233
      pos 10468
      pos 10505
      pos 10539
      pos 10615
      pos 10713
      pos 10797
      pos 10885
      pos 10920
      pos 11071
      pos 11104
      pos 11149
      pos 11245
      pos 11278
      pos 11312
      pos 11347
      pos 11403
      pos 11454
      pos 11498
      pos 11531
      pos 11561
      pos 11595
      pos 11651
      pos 11709
      pos 11730
      pos 11799
      pos 11820
      pos 11844
      pos 11864
      pos 11898
      pos 11920
      pos 11944
      pos 11963
      pos 12034
      pos 12069
      pos 12124
      pos 12163
      pos 12195
      pos 12217
      pos 12236
      pos 12255
      pos 12300
      pos 12333
      pos 12359
      pos 12384
      pos 12412
      pos 12437
      pos 12475
      pos 12499
      pos 12529
      pos 12573
      pos 12598
      pos 12630
      pos 12671
      pos 12724
      pos 12747
      pos 14448
      pos 14472
      pos 14508
      pos 14614
      pos 14638
      pos 14674
      pos 14698
      pos 14722
      pos 15871
    doc 2
      freq 1
      pos 4596
    doc 10
      freq 6
      pos 226
      pos 4764
      pos 7458
      pos 11494
      pos 13193
      pos 13205
    doc 11
      freq 6
      pos 130
      pos 529
      pos 1195
      pos 1407
      pos 9150
      pos 9688
    doc 13
      freq 3
      pos 1903
      pos 5224
      pos 5275
    doc 16
      freq 5
      pos 1274
      pos 1411
      pos 1414
      pos 1435
      pos 2614
    doc 17
      freq 5
      pos 476
      pos 487
      pos 777
      pos 779
      pos 2101
  term syntaxes
    doc 13
      freq 1
      pos 5470
  term synthesis
    doc 14
      freq 3
      pos 96
      pos 305
      pos 2402
  term synthesised
    doc 14
      freq 4
      pos 1806
      pos 1814
      pos 1853
      pos 2431
  term synthesising
    doc 14
      freq 2
      pos 2714
      pos 2772
  term synthesized
    doc 18
      freq 1
      pos 1912
  term sys6nrfwkbhtifabwtgdu7pbxrn5hsmn
    doc 10
      freq 1
      pos 12592
  term system
    doc 0
      freq 110
      pos 22
      pos 25
      pos 119
      pos 122
      pos 311
      pos 314
      pos 459
      pos 639
      pos 672
      pos 709
      pos 849
      pos 874
      pos 909
      pos 1274
      pos 1321
      pos 1380
      pos 1443
      pos 1461
      pos 2347
      pos 2366
      pos 2399
      pos 2509
      pos 2563
      pos 2738
      pos 2755
      pos 2891
      pos 2969
      pos 3055
      pos 3154
      pos 3192
      pos 3264
      pos 3294
      pos 3347
      pos 3384
      pos 3434
      pos 3506
      pos 3547
      pos 3565
      pos 3946
      pos 3977
      pos 4494
      pos 4535
      pos 4540
      pos 4576
      pos 4634
      pos 4645
      pos 4665
      pos 4775
      pos 4796
      pos 4852
      pos 5074
      pos 5116
      pos 5128
      pos 5375
      pos 5426
      pos 5454
      pos 6323
      pos 6485
      pos 6522
      pos 6578
      pos 6599
      pos 6604
      pos 6677
      pos 6736
      pos 6748
      pos 6757
      pos 6959
      pos 7196
      pos 7213
      pos 7219
      pos 7234
      pos 7405
      pos 7438
      pos 7644
      pos 7766
      pos 7794
      pos 8074
      pos 8116
      pos 8169
      pos 8866
      pos 8869
      pos 8956
      pos 9066
      pos 9110
      pos 9130
      pos 9136
      pos 9304
      pos 9310
      pos 9467
      pos 9650
      pos 9874
      pos 9962
      pos 10876
      pos 11751
      pos 11892
      pos 12090
      pos 12323
      pos 12424
      pos 12620
      pos 12801
      pos 12847
      pos 13095
      pos 13355
      pos 13397
      pos 14103
      pos 16295
      pos 16889
      pos 16892
      pos 17158
      pos 17161
    doc 1
      freq 4
      pos 584
      pos 6384
      pos 6455
      pos 8167
    doc 2
      freq 1
      pos 2133
    doc 3
      freq 1
      pos 1594
    doc 5
      freq 1
      pos 4278
    doc 6
      freq 1
      pos 493
    doc 7
      freq 2
      pos 1663
      pos 2596
    doc 10
      freq 3
      pos 867
      pos 11277
      pos 13354
    doc 12
      freq 13
      pos 76
      pos 1452
      pos 3256
      pos 3287
      pos 3303
      pos 3318
      pos 3323
      pos 3331
      pos 3394
      pos 7027
      pos 7115
      pos 7219
      pos 7246
    doc 13
      freq 15
      pos 783
      pos 2115
      pos 2608
      pos 2723
      pos 3687
      pos 3979
      pos 4071
      pos 4277
      pos 4379
      pos 4748
      pos 5205
      pos 5279
      pos 6568
      pos 6674
      pos 6706
    doc 15
      freq 2
      pos 1247
      pos 1489
    doc 17
      freq 1
      pos 1440
    skipList 
      level 0
        skipDoc 10
        skipDocFP 2223273
        impacts 
          impact 
            freq 2
            norm 100
          impact 
            freq 4
            norm 113
          impact 
            freq 110
            norm 120
        impactsEnd 
  term system's
    doc 0
      freq 1
      pos 7589
  term systematic
    doc 12
      freq 1
      pos 6582
  term systemid
    doc 0
      freq 5
      pos 1489
      pos 1515
      pos 2458
      pos 13294
      pos 14230
  term systems
    doc 0
      freq 17
      pos 515
      pos 583
      pos 772
      pos 790
      pos 809
      pos 3390
      pos 4446
      pos 8842
      pos 9388
      pos 9419
      pos 9574
      pos 9618
      pos 9811
      pos 9843
      pos 13391
      pos 16922
      pos 16924
    doc 1
      freq 6
      pos 16
      pos 9203
      pos 9234
      pos 9383
      pos 9508
      pos 9561
    doc 2
      freq 6
      pos 2417
      pos 2533
      pos 2589
      pos 2630
      pos 2667
      pos 2726
    doc 3
      freq 7
      pos 16
      pos 4420
      pos 4769
      pos 4904
      pos 4918
      pos 5873
      pos 5926
    doc 4
      freq 2
      pos 17
      pos 6061
    doc 6
      freq 4
      pos 16
      pos 2993
      pos 3164
      pos 3201
    doc 7
      freq 4
      pos 10
      pos 17
      pos 2901
      pos 2922
    doc 8
      freq 2
      pos 10
      pos 2132
    doc 10
      freq 3
      pos 16
      pos 9968
      pos 13432
    doc 11
      freq 5
      pos 11
      pos 24
      pos 9345
      pos 10531
      pos 10567
    doc 13
      freq 4
      pos 2369
      pos 4617
      pos 5240
      pos 6695
    doc 15
      freq 2
      pos 1056
      pos 3115
    doc 17
      freq 2
      pos 2015
      pos 2133
    skipList 
      level 0
        skipDoc 8
        skipDocFP 2226395
        impacts 
          impact 
            freq 2
            norm 97
          impact 
            freq 4
            norm 100
          impact 
            freq 7
            norm 107
          impact 
            freq 17
            norm 120
        impactsEnd 
  term t
    doc 1
      freq 2
      pos 25
      pos 8941
    doc 2
      freq 1
      pos 2971
    doc 3
      freq 6
      pos 4368
      pos 4537
      pos 4595
      pos 4663
      pos 4700
      pos 4903
    doc 4
      freq 3
      pos 1969
      pos 1976
      pos 5195
    doc 5
      freq 1
      pos 4143
    doc 6
      freq 1
      pos 3045
    doc 8
      freq 5
      pos 1727
      pos 1794
      pos 1814
      pos 2018
      pos 2066
    doc 9
      freq 1
      pos 1743
    doc 10
      freq 4
      pos 6391
      pos 6516
      pos 6691
      pos 12785
    doc 11
      freq 25
      pos 1546
      pos 2264
      pos 3182
      pos 3368
      pos 3415
      pos 4058
      pos 4323
      pos 4504
      pos 4718
      pos 5209
      pos 5366
      pos 5514
      pos 5674
      pos 5994
      pos 6218
      pos 6696
      pos 7242
      pos 8198
      pos 8527
      pos 9122
      pos 9299
      pos 9677
      pos 10112
      pos 10138
      pos 10237
    doc 12
      freq 8
      pos 7076
      pos 7125
      pos 7179
      pos 7206
      pos 7372
      pos 7546
      pos 7627
      pos 7681
    doc 13
      freq 1
      pos 6894
    doc 15
      freq 4
      pos 3
      pos 3913
      pos 3945
      pos 3980
    doc 17
      freq 3
      pos 496
      pos 2002
      pos 2125
    skipList 
      level 0
        skipDoc 9
        skipDocFP 2227991
        impacts 
          impact 
            freq 1
            norm 95
          impact 
            freq 5
            norm 97
          impact 
            freq 6
            norm 107
        impactsEnd 
  term t07rp0aj
    doc 11
      freq 1
      pos 10178
  term t1
    doc 1
      freq 1
      pos 693
    doc 8
      freq 1
      pos 745
    doc 11
      freq 1
      pos 3642
  term t1.105
    doc 1
      freq 1
      pos 9131
  term t2
    doc 11
      freq 1
      pos 3650
  term t2n
    doc 11
      freq 1
      pos 10546
  term t3
    doc 1
      freq 1
      pos 695
    doc 8
      freq 1
      pos 760
    doc 11
      freq 1
      pos 3658
  term t4
    doc 11
      freq 1
      pos 3666
  term t5
    doc 11
      freq 1
      pos 3674
  term t8k5
    doc 11
      freq 1
      pos 10167
  term t_r
    doc 5
      freq 6
      pos 2298
      pos 2314
      pos 2349
      pos 2396
      pos 2413
      pos 2426
  term t_s
    doc 5
      freq 3
      pos 2379
      pos 2405
      pos 2425
  term ta
    doc 11
      freq 1
      pos 10188
  term table
    doc 0
      freq 77
      pos 138
      pos 464
      pos 495
      pos 518
      pos 529
      pos 550
      pos 574
      pos 589
      pos 624
      pos 642
      pos 673
      pos 732
      pos 746
      pos 762
      pos 780
      pos 799
      pos 836
      pos 838
      pos 860
      pos 862
      pos 886
      pos 893
      pos 895
      pos 916
      pos 918
      pos 937
      pos 2237
      pos 3030
      pos 3078
      pos 3204
      pos 3319
      pos 3325
      pos 3490
      pos 3494
      pos 3644
      pos 3984
      pos 4026
      pos 4056
      pos 4160
      pos 4435
      pos 4636
      pos 4638
      pos 5365
      pos 5383
      pos 5397
      pos 5419
      pos 5535
      pos 6260
      pos 6262
      pos 8797
      pos 8809
      pos 8837
      pos 9372
      pos 9378
      pos 9409
      pos 9524
      pos 9558
      pos 9564
      pos 9608
      pos 9696
      pos 9795
      pos 9801
      pos 9833
      pos 9945
      pos 9983
      pos 10862
      pos 10897
      pos 10952
      pos 11002
      pos 11690
      pos 11693
      pos 11701
      pos 11721
      pos 11980
      pos 12058
      pos 12279
      pos 12284
    doc 1
      freq 1
      pos 211
    doc 2
      freq 1
      pos 112
    doc 3
      freq 3
      pos 176
      pos 2777
      pos 5655
    doc 4
      freq 2
      pos 148
      pos 2298
    doc 5
      freq 2
      pos 254
      pos 1885
    doc 7
      freq 1
      pos 112
    doc 8
      freq 1
      pos 105
    doc 9
      freq 1
      pos 114
    doc 10
      freq 3
      pos 178
      pos 5777
      pos 5847
    doc 11
      freq 1
      pos 95
    doc 12
      freq 1
      pos 145
    doc 13
      freq 1
      pos 132
    doc 14
      freq 1
      pos 118
    doc 15
      freq 1
      pos 200
    doc 18
      freq 1
      pos 149
    skipList 
      level 0
        skipDoc 8
        skipDocFP 2230444
        impacts 
          impact 
            freq 1
            norm 97
          impact 
            freq 2
            norm 104
          impact 
            freq 3
            norm 107
          impact 
            freq 77
            norm 120
        impactsEnd 
        skipDoc 18
        skipDocFP 2231928
        impacts 
          impact 
            freq 1
            norm 95
          impact 
            freq 3
            norm 116
        impactsEnd 
  term tables
    doc 0
      freq 3
      pos 134
      pos 332
      pos 1147
    doc 4
      freq 1
      pos 2338
  term tacacs
    doc 7
      freq 2
      pos 1379
      pos 1886
  term tag
    doc 3
      freq 40
      pos 1146
      pos 1149
      pos 1182
      pos 1195
      pos 1201
      pos 1392
      pos 1482
      pos 2046
      pos 2066
      pos 2343
      pos 2351
      pos 2359
      pos 2375
      pos 2438
      pos 2447
      pos 2470
      pos 2504
      pos 2558
      pos 2578
      pos 2589
      pos 2641
      pos 2663
      pos 2681
      pos 2714
      pos 2720
      pos 2726
      pos 2753
      pos 2791
      pos 2801
      pos 2811
      pos 2813
      pos 3799
      pos 5082
      pos 5083
      pos 5086
      pos 5087
      pos 5096
      pos 5098
      pos 5101
      pos 5240
    doc 4
      freq 2
      pos 4870
      pos 4897
    doc 10
      freq 8
      pos 6342
      pos 6627
      pos 6992
      pos 6998
      pos 7129
      pos 7135
      pos 7342
      pos 7348
    doc 11
      freq 60
      pos 842
      pos 1460
      pos 1467
      pos 1743
      pos 1976
      pos 2211
      pos 2371
      pos 2569
      pos 2686
      pos 2768
      pos 2848
      pos 3339
      pos 3374
      pos 3521
      pos 3624
      pos 3820
      pos 4026
      pos 4031
      pos 4149
      pos 4154
      pos 4282
      pos 4461
      pos 4677
      pos 4919
      pos 5043
      pos 5165
      pos 5323
      pos 5461
      pos 5468
      pos 5632
      pos 5809
      pos 5942
      pos 6164
      pos 6354
      pos 6456
      pos 6617
      pos 6693
      pos 6774
      pos 6816
      pos 6866
      pos 6987
      pos 6992
      pos 7111
      pos 7387
      pos 7518
      pos 7646
      pos 7744
      pos 7861
      pos 8048
      pos 8158
      pos 8169
      pos 8334
      pos 8495
      pos 8500
      pos 8612
      pos 8743
      pos 8833
      pos 8924
      pos 9079
      pos 9196
  term tag1
    doc 3
      freq 1
      pos 5063
  term tag2
    doc 3
      freq 2
      pos 5064
      pos 5258
  term tagged
    doc 3
      freq 12
      pos 201
      pos 226
      pos 1131
      pos 1134
      pos 1524
      pos 1696
      pos 1714
      pos 1839
      pos 2328
      pos 2544
      pos 2698
      pos 2806
    doc 4
      freq 1
      pos 4946
    doc 8
      freq 1
      pos 652
    doc 16
      freq 3
      pos 1201
      pos 1218
      pos 2489
  term tags
    doc 3
      freq 7
      pos 999
      pos 1823
      pos 2404
      pos 2493
      pos 2615
      pos 2647
      pos 2770
    doc 11
      freq 3
      pos 894
      pos 909
      pos 1031
    doc 17
      freq 1
      pos 2195
  term tahamilt
    doc 1
      freq 1
      pos 9248
  term tai
    doc 1
      freq 14
      pos 2372
      pos 3523
      pos 3546
      pos 3554
      pos 3580
      pos 4340
      pos 4444
      pos 4473
      pos 4529
      pos 4551
      pos 4652
      pos 4676
      pos 4772
      pos 7866
  term taii
    doc 1
      freq 15
      pos 3499
      pos 3527
      pos 3541
      pos 3699
      pos 3750
      pos 3824
      pos 3876
      pos 3895
      pos 3920
      pos 4315
      pos 4411
      pos 4624
      pos 4792
      pos 5539
      pos 7215
  term tak3c3t7a08crgokyjpuzmrv7k5phk7i5bqyoambncdlxumh9zmd2sl8fg
    doc 10
      freq 1
      pos 12480
  term take
    doc 0
      freq 1
      pos 2150
    doc 4
      freq 1
      pos 2043
    doc 6
      freq 1
      pos 1344
    doc 7
      freq 1
      pos 1552
    doc 9
      freq 1
      pos 478
    doc 11
      freq 4
      pos 2326
      pos 3718
      pos 4610
      pos 5129
    doc 12
      freq 1
      pos 846
    doc 15
      freq 1
      pos 3588
    doc 16
      freq 1
      pos 244
    doc 18
      freq 2
      pos 321
      pos 1563
    skipList 
      level 0
        skipDoc 15
        skipDocFP 2236137
        impacts 
          impact 
            freq 1
            norm 95
          impact 
            freq 4
            norm 114
        impactsEnd 
  term taken
    doc 1
      freq 2
      pos 6978
      pos 7414
    doc 2
      freq 1
      pos 1323
    doc 5
      freq 1
      pos 1891
    doc 6
      freq 1
      pos 2787
    doc 10
      freq 3
      pos 5350
      pos 5363
      pos 5377
    doc 12
      freq 1
      pos 2785
    doc 14
      freq 1
      pos 2486
  term takes
    doc 0
      freq 2
      pos 2180
      pos 17336
    doc 1
      freq 1
      pos 9717
    doc 2
      freq 1
      pos 6514
    doc 3
      freq 1
      pos 6066
    doc 4
      freq 1
      pos 6221
    doc 5
      freq 1
      pos 4551
    doc 6
      freq 1
      pos 3351
    doc 7
      freq 1
      pos 3056
    doc 8
      freq 1
      pos 2273
    doc 9
      freq 1
      pos 1918
    doc 10
      freq 2
      pos 2357
      pos 13579
    doc 11
      freq 1
      pos 10740
    doc 12
      freq 1
      pos 9590
    doc 13
      freq 1
      pos 7205
    doc 14
      freq 1
      pos 5671
    doc 15
      freq 2
      pos 2952
      pos 4190
    doc 16
      freq 2
      pos 271
      pos 2801
    doc 17
      freq 1
      pos 2525
    doc 18
      freq 1
      pos 2313
    skipList 
      level 0
        skipDoc 7
        skipDocFP 2237143
        impacts 
          impact 
            freq 1
            norm 100
          impact 
            freq 2
            norm 120
        impactsEnd 
        skipDoc 15
        skipDocFP 2237463
        impacts 
          impact 
            freq 1
            norm 95
          impact 
            freq 2
            norm 104
        impactsEnd 
  term taking
    doc 2
      freq 1
      pos 3910
    doc 12
      freq 1
      pos 4033
  term tamper
    doc 13
      freq 2
      pos 7017
      pos 7033
    doc 17
      freq 1
      pos 1476
  term tampering
    doc 5
      freq 1
      pos 1036
  term tandberg
    doc 6
      freq 1
      pos 3132
  term tao
    doc 10
      freq 1
      pos 12170
  term tappan
    doc 1
      freq 3
      pos 8932
      pos 9381
      pos 9392
    doc 3
      freq 3
      pos 4365
      pos 4767
      pos 4778
    doc 8
      freq 1
      pos 2057
  term taps
    doc 6
      freq 1
      pos 2609
  term tar
    doc 10
      freq 2
      pos 12194
      pos 12377
    doc 11
      freq 2
      pos 9746
      pos 9794
  term target
    doc 1
      freq 3
      pos 3473
      pos 3495
      pos 3521
    doc 10
      freq 3
      pos 3414
      pos 3435
      pos 3462
    doc 11
      freq 2
      pos 5786
      pos 5803
    doc 13
      freq 1
      pos 1895
  term targeted
    doc 5
      freq 1
      pos 660
    doc 6
      freq 1
      pos 830
  term targeting
    doc 5
      freq 1
      pos 165
  term targets
    doc 10
      freq 1
      pos 8398
  term task
    doc 0
      freq 1
      pos 17293
    doc 1
      freq 1
      pos 9674
    doc 2
      freq 3
      pos 435
      pos 3749
      pos 6471
    doc 3
      freq 1
      pos 6023
    doc 4
      freq 1
      pos 6178
    doc 5
      freq 1
      pos 4508
    doc 6
      freq 1
      pos 3308
    doc 7
      freq 1
      pos 3013
    doc 8
      freq 1
      pos 2230
    doc 9
      freq 1
      pos 1875
    doc 10
      freq 1
      pos 13536
    doc 11
      freq 1
      pos 10697
    doc 12
      freq 1
      pos 9547
    doc 13
      freq 1
      pos 7162
    doc 14
      freq 1
      pos 5628
    doc 15
      freq 1
      pos 4147
    doc 16
      freq 1
      pos 2758
    doc 17
      freq 1
      pos 2482
    doc 18
      freq 1
      pos 2270
    skipList 
      level 0
        skipDoc 7
        skipDocFP 2239529
        impacts 
          impact 
            freq 1
            norm 100
          impact 
            freq 3
            norm 108
        impactsEnd 
        skipDoc 15
        skipDocFP 2239863
        impacts 
          impact 
            freq 1
            norm 95
        impactsEnd 
  term tasman
    doc 1
      freq 1
      pos 9238
    doc 4
      freq 1
      pos 6065
    doc 10
      freq 1
      pos 13435
  term tatuy
    doc 4
      freq 1
      pos 5494
    doc 12
      freq 1
      pos 6807
  term taxonomy
    doc 2
      freq 2
      pos 1768
      pos 3313
  term taylor
    doc 11
      freq 1
      pos 9495
  term tc
    doc 0
      freq 2
      pos 391
      pos 1018
    doc 12
      freq 14
      pos 7624
      pos 7632
      pos 8321
      pos 8352
      pos 8469
      pos 8522
      pos 8565
      pos 8581
      pos 8591
      pos 8613
      pos 8661
      pos 8678
      pos 8787
      pos 8895
  term tcp
    doc 0
      freq 1
      pos 16971
    doc 4
      freq 4
      pos 4589
      pos 4592
      pos 5438
      pos 5445
    doc 7
      freq 3
      pos 1960
      pos 1978
      pos 2076
    doc 11
      freq 47
      pos 1512
      pos 1935
      pos 2578
      pos 2922
      pos 2928
      pos 2934
      pos 2940
      pos 2946
      pos 2952
      pos 2958
      pos 2964
      pos 2970
      pos 2976
      pos 2982
      pos 2988
      pos 2994
      pos 3000
      pos 3006
      pos 3012
      pos 3018
      pos 3024
      pos 3030
      pos 3036
      pos 3042
      pos 3062
      pos 3068
      pos 3074
      pos 3080
      pos 3086
      pos 3092
      pos 3098
      pos 3104
      pos 3110
      pos 3116
      pos 3122
      pos 3128
      pos 3135
      pos 3673
      pos 4399
      pos 4569
      pos 4908
      pos 5029
      pos 5796
      pos 7401
      pos 7532
      pos 8062
      pos 8299
    doc 12
      freq 5
      pos 8340
      pos 8486
      pos 8869
      pos 8889
      pos 9129
    doc 16
      freq 2
      pos 1961
      pos 2329
  term tdm
    doc 1
      freq 16
      pos 569
      pos 572
      pos 588
      pos 604
      pos 627
      pos 660
      pos 663
      pos 676
      pos 681
      pos 713
      pos 723
      pos 1076
      pos 1081
      pos 2363
      pos 7853
      pos 9006
    doc 8
      freq 7
      pos 777
      pos 1041
      pos 1060
      pos 1087
      pos 1896
      pos 2024
      pos 2046
  term tdmoip
    doc 8
      freq 8
      pos 771
      pos 774
      pos 782
      pos 785
      pos 1045
      pos 1064
      pos 1089
      pos 2036
  term te
    doc 0
      freq 1
      pos 16360
  term te3gcqnfq
    doc 11
      freq 1
      pos 10240
  term team
    doc 11
      freq 1
      pos 9581
  term technical
    doc 2
      freq 1
      pos 4831
    doc 12
      freq 1
      pos 7516
    doc 17
      freq 1
      pos 1473
  term techniqu
    doc 11
      freq 1
      pos 4615
    doc 12
      freq 2
      pos 2113
      pos 2127
    doc 13
      freq 1
      pos 4645
    doc 14
      freq 2
      pos 307
      pos 543
    doc 18
      freq 10
      pos 159
      pos 362
      pos 415
      pos 417
      pos 489
      pos 554
      pos 568
      pos 870
      pos 1588
      pos 1842
  term techniques
    doc 14
      freq 1
      pos 2562
    doc 17
      freq 1
      pos 1689
    doc 18
      freq 2
      pos 954
      pos 1967
  term technologies
    doc 6
      freq 4
      pos 10
      pos 3102
      pos 3138
      pos 3183
    doc 13
      freq 1
      pos 3143
  term technology
    doc 0
      freq 2
      pos 17365
      pos 17506
    doc 1
      freq 3
      pos 9316
      pos 9746
      pos 9887
    doc 2
      freq 5
      pos 2527
      pos 2583
      pos 2624
      pos 6543
      pos 6684
    doc 3
      freq 5
      pos 1020
      pos 4414
      pos 4817
      pos 6095
      pos 6236
    doc 4
      freq 2
      pos 6250
      pos 6391
    doc 5
      freq 2
      pos 4580
      pos 4721
    doc 6
      freq 2
      pos 3380
      pos 3521
    doc 7
      freq 2
      pos 3085
      pos 3226
    doc 8
      freq 2
      pos 2302
      pos 2443
    doc 9
      freq 2
      pos 1947
      pos 2088
    doc 10
      freq 2
      pos 13608
      pos 13749
    doc 11
      freq 2
      pos 10769
      pos 10910
    doc 12
      freq 2
      pos 9619
      pos 9760
    doc 13
      freq 4
      pos 24
      pos 7044
      pos 7234
      pos 7375
    doc 14
      freq 2
      pos 5700
      pos 5841
    doc 15
      freq 4
      pos 22
      pos 4051
      pos 4219
      pos 4360
    doc 16
      freq 2
      pos 2830
      pos 2971
    doc 17
      freq 4
      pos 2013
      pos 2131
      pos 2554
      pos 2695
    doc 18
      freq 2
      pos 2342
      pos 2483
    skipList 
      level 0
        skipDoc 7
        skipDocFP 2243887
        impacts 
          impact 
            freq 2
            norm 100
          impact 
            freq 5
            norm 107
        impactsEnd 
        skipDoc 15
        skipDocFP 2244418
        impacts 
          impact 
            freq 2
            norm 95
          impact 
            freq 4
            norm 104
        impactsEnd 
  term ted
    doc 15
      freq 1
      pos 3847
  term teeivuhkmwyu
    doc 11
      freq 1
      pos 3808
  term tel
    doc 3
      freq 1
      pos 4923
    doc 10
      freq 13
      pos 259
      pos 2441
      pos 4462
      pos 4490
      pos 7394
      pos 7461
      pos 7486
      pos 7508
      pos 7534
      pos 7565
      pos 7620
      pos 7700
      pos 13316
  term telecom
    doc 1
      freq 2
      pos 9253
      pos 9269
    doc 3
      freq 1
      pos 4783
  term telecommunication
    doc 6
      freq 1
      pos 885
  term telecommunications
    doc 2
      freq 4
      pos 2528
      pos 2584
      pos 2625
      pos 2662
    doc 3
      freq 1
      pos 4415
  term telephon
    doc 10
      freq 9
      pos 610
      pos 665
      pos 748
      pos 7408
      pos 7435
      pos 7636
      pos 7741
      pos 7757
      pos 13319
  term television
    doc 6
      freq 2
      pos 880
      pos 3133
    doc 13
      freq 1
      pos 625
  term tellabs
    doc 1
      freq 3
      pos 32
      pos 9285
      pos 9541
    doc 3
      freq 3
      pos 27
      pos 4754
      pos 5906
  term tellabs.com
    doc 1
      freq 2
      pos 9296
      pos 9556
    doc 3
      freq 2
      pos 4765
      pos 5921
  term tells
    doc 10
      freq 1
      pos 2007
  term telnet
    doc 7
      freq 22
      pos 1348
      pos 1375
      pos 1835
      pos 1846
      pos 1850
      pos 1856
      pos 1862
      pos 1867
      pos 1873
      pos 1879
      pos 1889
      pos 1895
      pos 1899
      pos 1912
      pos 1918
      pos 1927
      pos 1934
      pos 1940
      pos 1946
      pos 1952
      pos 2106
      pos 2506
  term templin
    doc 4
      freq 1
      pos 5501
  term temporary
    doc 12
      freq 4
      pos 198
      pos 1323
      pos 1325
      pos 1360
  term temptation
    doc 12
      freq 1
      pos 9065
  term tempting
    doc 12
      freq 1
      pos 8715
  term ten
    doc 10
      freq 2
      pos 3173
      pos 3197
    doc 13
      freq 1
      pos 370
  term tend
    doc 13
      freq 1
      pos 2437
  term tends
    doc 13
      freq 1
      pos 4712
    doc 18
      freq 1
      pos 1691
  term tentatively
    doc 18
      freq 1
      pos 536
  term tenths
    doc 6
      freq 1
      pos 1367
  term ter
    doc 3
      freq 2
      pos 875
      pos 892
  term tered
    doc 12
      freq 2
      pos 1582
      pos 7610
  term term
    doc 1
      freq 1
      pos 3107
    doc 4
      freq 2
      pos 1938
      pos 4686
    doc 6
      freq 3
      pos 548
      pos 1106
      pos 2382
    doc 10
      freq 2
      pos 7721
      pos 11323
    doc 12
      freq 2
      pos 2444
      pos 4500
    doc 13
      freq 1
      pos 1223
    doc 15
      freq 2
      pos 3558
      pos 3584
  term termed
    doc 0
      freq 1
      pos 231
    doc 12
      freq 1
      pos 8206
  term terminal
    doc 7
      freq 4
      pos 1900
      pos 1921
      pos 1941
      pos 1947
    doc 13
      freq 1
      pos 3605
  term terminals
    doc 13
      freq 3
      pos 3135
      pos 3178
      pos 3268
  term terminat
    doc 10
      freq 1
      pos 7197
  term terminates
    doc 3
      freq 1
      pos 915
  term terminating
    doc 3
      freq 1
      pos 5317
    doc 11
      freq 2
      pos 5118
      pos 5730
  term termination
    doc 3
      freq 6
      pos 861
      pos 988
      pos 1087
      pos 1160
      pos 1167
      pos 2138
    doc 6
      freq 1
      pos 1043
  term terminations
    doc 3
      freq 1
      pos 1073
  term terminology
    doc 3
      freq 2
      pos 1214
      pos 4708
    doc 4
      freq 1
      pos 392
    doc 5
      freq 2
      pos 261
      pos 1045
    doc 9
      freq 1
      pos 374
    doc 10
      freq 2
      pos 185
      pos 670
    doc 13
      freq 2
      pos 150
      pos 1181
  term terms
    doc 5
      freq 1
      pos 577
    doc 6
      freq 2
      pos 1336
      pos 2211
    doc 9
      freq 1
      pos 1615
    doc 11
      freq 2
      pos 1301
      pos 1373
    doc 13
      freq 4
      pos 154
      pos 500
      pos 1214
      pos 1329
    doc 17
      freq 1
      pos 943
  term terrestrial
    doc 13
      freq 1
      pos 547
  term tesla
    doc 5
      freq 111
      pos 24
      pos 86
      pos 101
      pos 124
      pos 142
      pos 153
      pos 183
      pos 206
      pos 216
      pos 251
      pos 264
      pos 281
      pos 354
      pos 472
      pos 474
      pos 508
      pos 545
      pos 574
      pos 582
      pos 698
      pos 726
      pos 739
      pos 790
      pos 860
      pos 864
      pos 894
      pos 906
      pos 920
      pos 928
      pos 937
      pos 950
      pos 960
      pos 992
      pos 1005
      pos 1029
      pos 1077
      pos 1095
      pos 1147
      pos 1161
      pos 1213
      pos 1223
      pos 1239
      pos 1246
      pos 1296
      pos 1327
      pos 1337
      pos 1372
      pos 1478
      pos 1491
      pos 1531
      pos 1537
      pos 1714
      pos 1745
      pos 1864
      pos 1872
      pos 1931
      pos 1938
      pos 2048
      pos 2096
      pos 2108
      pos 2122
      pos 2135
      pos 2163
      pos 2272
      pos 2359
      pos 2406
      pos 2556
      pos 2703
      pos 2707
      pos 2737
      pos 2762
      pos 2773
      pos 2787
      pos 2793
      pos 2813
      pos 2844
      pos 2880
      pos 2946
      pos 2952
      pos 2955
      pos 2967
      pos 3051
      pos 3122
      pos 3222
      pos 3339
      pos 3361
      pos 3500
      pos 3662
      pos 3676
      pos 3840
      pos 3842
      pos 3870
      pos 3874
      pos 3914
      pos 3925
      pos 3934
      pos 3947
      pos 3952
      pos 3958
      pos 3970
      pos 3985
      pos 3989
      pos 4040
      pos 4044
      pos 4047
      pos 4055
      pos 4114
      pos 4200
      pos 4225
      pos 4350
      pos 4435
  term test
    doc 9
      freq 1
      pos 183
    doc 10
      freq 1
      pos 13397
    doc 11
      freq 63
      pos 36
      pos 85
      pos 124
      pos 193
      pos 496
      pos 549
      pos 576
      pos 618
      pos 621
      pos 721
      pos 725
      pos 823
      pos 1049
      pos 1190
      pos 1256
      pos 1442
      pos 1576
      pos 1900
      pos 2114
      pos 2294
      pos 2546
      pos 2787
      pos 3055
      pos 3322
      pos 3445
      pos 3690
      pos 3886
      pos 3987
      pos 4173
      pos 4413
      pos 4656
      pos 4894
      pos 5072
      pos 5239
      pos 5396
      pos 5544
      pos 5704
      pos 5836
      pos 6024
      pos 6248
      pos 6484
      pos 6720
      pos 6934
      pos 7144
      pos 7272
      pos 7550
      pos 7784
      pos 8031
      pos 8228
      pos 8460
      pos 8644
      pos 8863
      pos 8962
      pos 9207
      pos 9417
      pos 9724
      pos 9735
      pos 9862
      pos 10028
      pos 10218
      pos 10427
      pos 10520
      pos 10623
    doc 12
      freq 4
      pos 2480
      pos 7625
      pos 8523
      pos 8679
    doc 14
      freq 3
      pos 171
      pos 1763
      pos 1792
    doc 17
      freq 1
      pos 120
    doc 18
      freq 2
      pos 1046
      pos 1603
  term testbeds
    doc 15
      freq 1
      pos 3085
  term tested
    doc 12
      freq 1
      pos 8529
    doc 14
      freq 1
      pos 5312
  term testing
    doc 9
      freq 1
      pos 540
    doc 10
      freq 1
      pos 6101
    doc 12
      freq 1
      pos 8514
    doc 14
      freq 2
      pos 5285
      pos 5318
  term tests
    doc 9
      freq 1
      pos 268
    doc 10
      freq 2
      pos 230
      pos 5941
    doc 11
      freq 6
      pos 129
      pos 1194
      pos 7008
      pos 7155
      pos 7679
      pos 9403
    doc 14
      freq 1
      pos 2259
  term text
    doc 1
      freq 1
      pos 6271
    doc 2
      freq 1
      pos 1429
    doc 4
      freq 1
      pos 6013
    doc 8
      freq 2
      pos 942
      pos 961
    doc 9
      freq 1
      pos 1640
    doc 10
      freq 2
      pos 12187
      pos 12352
    doc 11
      freq 7
      pos 735
      pos 782
      pos 3859
      pos 8354
      pos 9089
      pos 9739
      pos 9769
    doc 13
      freq 2
      pos 1314
      pos 1901
    doc 16
      freq 28
      pos 201
      pos 616
      pos 750
      pos 1453
      pos 1485
      pos 1488
      pos 1490
      pos 1498
      pos 1517
      pos 1520
      pos 1531
      pos 1547
      pos 1734
      pos 1788
      pos 1816
      pos 1833
      pos 1878
      pos 1941
      pos 2030
      pos 2077
      pos 2145
      pos 2169
      pos 2197
      pos 2210
      pos 2309
      pos 2405
      pos 2424
      pos 2441
    doc 17
      freq 3
      pos 1168
      pos 1238
      pos 1246
    skipList 
      level 0
        skipDoc 13
        skipDocFP 2253304
        impacts 
          impact 
            freq 1
            norm 95
          impact 
            freq 2
            norm 97
          impact 
            freq 7
            norm 114
        impactsEnd 
  term textual
    doc 0
      freq 22
      pos 1011
      pos 1410
      pos 1433
      pos 1497
      pos 1582
      pos 1602
      pos 1634
      pos 1656
      pos 1701
      pos 1746
      pos 1797
      pos 1827
      pos 1853
      pos 1884
      pos 1910
      pos 1950
      pos 1971
      pos 1994
      pos 2021
      pos 2056
      pos 17068
      pos 17118
    doc 13
      freq 2
      pos 3115
      pos 3172
    doc 17
      freq 2
      pos 1123
      pos 1197
  term thaler
    doc 15
      freq 1
      pos 3858
  term than
    doc 0
      freq 12
      pos 1473
      pos 2575
      pos 2589
      pos 2836
      pos 2914
      pos 3107
      pos 3648
      pos 4164
      pos 11006
      pos 13386
      pos 13880
      pos 13969
    doc 1
      freq 6
      pos 2972
      pos 5049
      pos 5155
      pos 8186
      pos 8827
      pos 8854
    doc 2
      freq 9
      pos 736
      pos 1395
      pos 1500
      pos 1624
      pos 1889
      pos 2102
      pos 3661
      pos 3890
      pos 4400
    doc 3
      freq 4
      pos 709
      pos 2639
      pos 3465
      pos 4232
    doc 4
      freq 5
      pos 1092
      pos 2262
      pos 2402
      pos 2535
      pos 2881
    doc 7
      freq 3
      pos 479
      pos 1619
      pos 1638
    doc 9
      freq 3
      pos 293
      pos 1306
      pos 1412
    doc 10
      freq 11
      pos 663
      pos 1117
      pos 1418
      pos 3196
      pos 5007
      pos 5710
      pos 6070
      pos 7549
      pos 9367
      pos 10228
      pos 10616
    doc 11
      freq 8
      pos 258
      pos 886
      pos 1599
      pos 3927
      pos 4347
      pos 4361
      pos 5005
      pos 6949
    doc 12
      freq 14
      pos 1014
      pos 2087
      pos 2267
      pos 2458
      pos 4256
      pos 4792
      pos 4864
      pos 5441
      pos 5588
      pos 5655
      pos 6743
      pos 8942
      pos 8965
      pos 9354
    doc 13
      freq 11
      pos 518
      pos 2650
      pos 3750
      pos 3799
      pos 3815
      pos 3928
      pos 4639
      pos 4926
      pos 5414
      pos 6535
      pos 6587
    doc 14
      freq 22
      pos 499
      pos 503
      pos 920
      pos 955
      pos 974
      pos 1019
      pos 1173
      pos 1264
      pos 1305
      pos 1399
      pos 1421
      pos 1576
      pos 1598
      pos 1626
      pos 1671
      pos 2062
      pos 2689
      pos 2809
      pos 4978
      pos 5151
      pos 5289
      pos 5322
    doc 15
      freq 3
      pos 2992
      pos 3590
      pos 3618
    doc 16
      freq 1
      pos 1017
    doc 17
      freq 5
      pos 482
      pos 953
      pos 1346
      pos 1649
      pos 1938
    doc 18
      freq 6
      pos 110
      pos 552
      pos 638
      pos 1269
      pos 1895
      pos 1984
    skipList 
      level 0
        skipDoc 10
        skipDocFP 2255081
        impacts 
          impact 
            freq 3
            norm 95
          impact 
            freq 4
            norm 107
          impact 
            freq 9
            norm 108
          impact 
            freq 11
            norm 116
          impact 
            freq 12
            norm 120
        impactsEnd 
        skipDoc 18
        skipDocFP 2256064
        impacts 
          impact 
            freq 6
            norm 97
          impact 
            freq 22
            norm 107
        impactsEnd 
  term thank
    doc 0
      freq 1
      pos 15902
    doc 5
      freq 2
      pos 4070
      pos 4089
    doc 10
      freq 1
      pos 12108
    doc 13
      freq 1
      pos 6959
    doc 14
      freq 1
      pos 5342
    doc 15
      freq 2
      pos 3834
      pos 3884
    doc 18
      freq 1
      pos 2041
  term thanks
    doc 9
      freq 2
      pos 1622
      pos 1634
    doc 10
      freq 1
      pos 12165
    doc 11
      freq 2
      pos 9496
      pos 9524
    doc 16
      freq 2
      pos 1577
      pos 1590
  term that
    doc 0
      freq 94
      pos 205
      pos 273
      pos 499
      pos 924
      pos 940
      pos 1183
      pos 1544
      pos 2037
      pos 2072
      pos 2112
      pos 2156
      pos 2161
      pos 2178
      pos 2190
      pos 2211
      pos 2229
      pos 2255
      pos 2266
      pos 2270
      pos 2306
      pos 3391
      pos 3619
      pos 3987
      pos 4049
      pos 4069
      pos 4083
      pos 4135
      pos 4746
      pos 4885
      pos 4898
      pos 4916
      pos 5285
      pos 5565
      pos 6392
      pos 6571
      pos 6690
      pos 7050
      pos 7297
      pos 7640
      pos 7713
      pos 8071
      pos 8113
      pos 8166
      pos 9697
      pos 10262
      pos 10564
      pos 10751
      pos 10976
      pos 11620
      pos 12019
      pos 12287
      pos 12372
      pos 12403
      pos 12518
      pos 12716
      pos 12765
      pos 12859
      pos 12887
      pos 12934
      pos 12937
      pos 12978
      pos 13035
      pos 13141
      pos 13243
      pos 13460
      pos 13558
      pos 13650
      pos 13702
      pos 13752
      pos 13825
      pos 13877
      pos 13897
      pos 13966
      pos 13981
      pos 14037
      pos 14092
      pos 14166
      pos 14395
      pos 14408
      pos 14560
      pos 14574
      pos 15878
      pos 16102
      pos 16187
      pos 16200
      pos 16251
      pos 16719
      pos 16830
      pos 16869
      pos 17308
      pos 17352
      pos 17390
      pos 17503
      pos 17507
    doc 1
      freq 99
      pos 465
      pos 549
      pos 858
      pos 939
      pos 1002
      pos 1191
      pos 1216
      pos 1226
      pos 1230
      pos 1287
      pos 1320
      pos 1347
      pos 1422
      pos 1439
      pos 1456
      pos 1583
      pos 1679
      pos 1743
      pos 1786
      pos 1942
      pos 2132
      pos 2511
      pos 2633
      pos 2639
      pos 2737
      pos 2748
      pos 2784
      pos 2831
      pos 2847
      pos 2924
      pos 2932
      pos 3117
      pos 3147
      pos 3247
      pos 3283
      pos 3294
      pos 3432
      pos 3587
      pos 3733
      pos 3865
      pos 3974
      pos 4129
      pos 4161
      pos 4164
      pos 4480
      pos 4500
      pos 4614
      pos 4711
      pos 4735
      pos 4944
      pos 5316
      pos 5635
      pos 5781
      pos 5816
      pos 5945
      pos 5985
      pos 6163
      pos 6170
      pos 6207
      pos 6302
      pos 6416
      pos 6568
      pos 6608
      pos 6673
      pos 6716
      pos 6778
      pos 6803
      pos 6840
      pos 6880
      pos 6907
      pos 6989
      pos 7056
      pos 7077
      pos 7284
      pos 7432
      pos 7473
      pos 7531
      pos 7936
      pos 8045
      pos 8061
      pos 8071
      pos 8087
      pos 8201
      pos 8249
      pos 8259
      pos 8273
      pos 8284
      pos 8306
      pos 8348
      pos 8451
      pos 8536
      pos 8612
      pos 8762
      pos 8802
      pos 9689
      pos 9733
      pos 9771
      pos 9884
      pos 9888
    doc 2
      freq 37
      pos 93
      pos 310
      pos 381
      pos 544
      pos 913
      pos 1026
      pos 1131
      pos 1206
      pos 1232
      pos 1575
      pos 1611
      pos 1861
      pos 1961
      pos 2044
      pos 3783
      pos 3827
      pos 4149
      pos 4155
      pos 4163
      pos 4174
      pos 4385
      pos 4540
      pos 4611
      pos 5154
      pos 5267
      pos 5405
      pos 5412
      pos 5577
      pos 5675
      pos 5887
      pos 5898
      pos 5998
      pos 6486
      pos 6530
      pos 6568
      pos 6681
      pos 6685
    doc 3
      freq 45
      pos 386
      pos 435
      pos 560
      pos 834
      pos 938
      pos 944
      pos 975
      pos 982
      pos 1162
      pos 1599
      pos 1720
      pos 1757
      pos 1954
      pos 2037
      pos 2226
      pos 2357
      pos 2445
      pos 2631
      pos 2704
      pos 2739
      pos 2771
      pos 2781
      pos 2850
      pos 2930
      pos 2986
      pos 3064
      pos 3123
      pos 3334
      pos 3475
      pos 3533
      pos 3725
      pos 3763
      pos 4187
      pos 4198
      pos 4249
      pos 4266
      pos 5131
      pos 5140
      pos 5353
      pos 5609
      pos 6038
      pos 6082
      pos 6120
      pos 6233
      pos 6237
    doc 4
      freq 54
      pos 853
      pos 919
      pos 929
      pos 1037
      pos 1053
      pos 1064
      pos 1133
      pos 1168
      pos 1200
      pos 1398
      pos 1402
      pos 1450
      pos 1569
      pos 1715
      pos 1946
      pos 2251
      pos 2328
      pos 2370
      pos 2531
      pos 2586
      pos 2606
      pos 2639
      pos 2691
      pos 2872
      pos 3397
      pos 3492
      pos 3670
      pos 3836
      pos 3890
      pos 3974
      pos 3989
      pos 3998
      pos 4008
      pos 4153
      pos 4203
      pos 4373
      pos 4482
      pos 4597
      pos 4659
      pos 4766
      pos 4831
      pos 4906
      pos 4989
      pos 5608
      pos 5623
      pos 5733
      pos 5896
      pos 5927
      pos 6020
      pos 6193
      pos 6237
      pos 6275
      pos 6388
      pos 6392
    doc 5
      freq 31
      pos 112
      pos 182
      pos 372
      pos 399
      pos 606
      pos 631
      pos 711
      pos 747
      pos 834
      pos 947
      pos 973
      pos 984
      pos 1111
      pos 1339
      pos 1553
      pos 1627
      pos 1876
      pos 2229
      pos 2268
      pos 2449
      pos 3029
      pos 3098
      pos 3194
      pos 3342
      pos 3453
      pos 3545
      pos 4523
      pos 4567
      pos 4605
      pos 4718
      pos 4722
    doc 6
      freq 23
      pos 114
      pos 185
      pos 416
      pos 531
      pos 542
      pos 723
      pos 804
      pos 808
      pos 964
      pos 1005
      pos 1051
      pos 1300
      pos 1307
      pos 1501
      pos 1628
      pos 1682
      pos 2146
      pos 2793
      pos 3323
      pos 3367
      pos 3405
      pos 3518
      pos 3522
    doc 7
      freq 29
      pos 100
      pos 106
      pos 231
      pos 341
      pos 348
      pos 642
      pos 666
      pos 1155
      pos 1190
      pos 1201
      pos 1256
      pos 1290
      pos 1315
      pos 1323
      pos 1334
      pos 1376
      pos 1395
      pos 1458
      pos 1461
      pos 1493
      pos 1506
      pos 1605
      pos 1677
      pos 1734
      pos 3028
      pos 3072
      pos 3110
      pos 3223
      pos 3227
    doc 8
      freq 9
      pos 81
      pos 271
      pos 279
      pos 1096
      pos 2245
      pos 2289
      pos 2327
      pos 2440
      pos 2444
    doc 9
      freq 22
      pos 105
      pos 210
      pos 432
      pos 554
      pos 640
      pos 856
      pos 893
      pos 1121
      pos 1170
      pos 1182
      pos 1206
      pos 1226
      pos 1438
      pos 1489
      pos 1501
      pos 1517
      pos 1612
      pos 1890
      pos 1934
      pos 1972
      pos 2085
      pos 2089
    doc 10
      freq 211
      pos 112
      pos 492
      pos 519
      pos 574
      pos 633
      pos 750
      pos 777
      pos 910
      pos 1098
      pos 1105
      pos 1146
      pos 1152
      pos 1159
      pos 1227
      pos 1312
      pos 1334
      pos 1421
      pos 1462
      pos 1523
      pos 1552
      pos 1571
      pos 1674
      pos 1708
      pos 1765
      pos 1864
      pos 1872
      pos 1893
      pos 1966
      pos 1976
      pos 1989
      pos 2006
      pos 2039
      pos 2064
      pos 2128
      pos 2144
      pos 2158
      pos 2162
      pos 2196
      pos 2209
      pos 2220
      pos 2227
      pos 2238
      pos 2298
      pos 2628
      pos 2630
      pos 2657
      pos 2693
      pos 2714
      pos 2743
      pos 2811
      pos 2864
      pos 2870
      pos 2989
      pos 3011
      pos 3071
      pos 3147
      pos 3177
      pos 3269
      pos 3418
      pos 3426
      pos 3456
      pos 3568
      pos 3617
      pos 3847
      pos 4000
      pos 4041
      pos 4076
      pos 4081
      pos 4094
      pos 4220
      pos 4265
      pos 4283
      pos 4435
      pos 4465
      pos 4502
      pos 4574
      pos 4623
      pos 4997
      pos 5082
      pos 5105
      pos 5152
      pos 5237
      pos 5258
      pos 5260
      pos 5343
      pos 5639
      pos 5642
      pos 5849
      pos 5884
      pos 5896
      pos 6061
      pos 6154
      pos 6315
      pos 6439
      pos 6470
      pos 6576
      pos 6792
      pos 6954
      pos 7043
      pos 7062
      pos 7157
      pos 7185
      pos 7220
      pos 7294
      pos 7453
      pos 7624
      pos 7725
      pos 7755
      pos 7817
      pos 7833
      pos 7870
      pos 7895
      pos 7910
      pos 7939
      pos 7957
      pos 7985
      pos 8088
      pos 8109
      pos 8119
      pos 8185
      pos 8201
      pos 8219
      pos 8267
      pos 8395
      pos 8510
      pos 8597
      pos 8611
      pos 8634
      pos 8725
      pos 8763
      pos 8859
      pos 8954
      pos 8962
      pos 9110
      pos 9131
      pos 9158
      pos 9171
      pos 9197
      pos 9227
      pos 9233
      pos 9303
      pos 9309
      pos 9387
      pos 9399
      pos 9452
      pos 9503
      pos 9515
      pos 9607
      pos 9665
      pos 9692
      pos 9713
      pos 9866
      pos 9877
      pos 9929
      pos 9961
      pos 9969
      pos 10065
      pos 10088
      pos 10103
      pos 10117
      pos 10207
      pos 10400
      pos 10417
      pos 10483
      pos 10517
      pos 10520
      pos 10535
      pos 10549
      pos 10566
      pos 10575
      pos 10582
      pos 10641
      pos 10651
      pos 10830
      pos 10913
      pos 10922
      pos 10944
      pos 10960
      pos 11028
      pos 11044
      pos 11060
      pos 11066
      pos 11073
      pos 11114
      pos 11142
      pos 11148
      pos 11248
      pos 11259
      pos 11348
      pos 11355
      pos 11369
      pos 11433
      pos 11579
      pos 11588
      pos 11668
      pos 11877
      pos 11965
      pos 12048
      pos 12198
      pos 12231
      pos 12884
      pos 12897
      pos 12916
      pos 12937
      pos 13015
      pos 13042
      pos 13551
      pos 13595
      pos 13633
      pos 13746
      pos 13750
    doc 11
      freq 46
      pos 698
      pos 704
      pos 833
      pos 978
      pos 1291
      pos 1618
      pos 1714
      pos 1769
      pos 1800
      pos 2042
      pos 2078
      pos 2472
      pos 2654
      pos 2726
      pos 3264
      pos 3285
      pos 3495
      pos 4197
      pos 4358
      pos 4589
      pos 4861
      pos 4983
      pos 5131
      pos 5579
      pos 5745
      pos 6068
      pos 6289
      pos 6337
      pos 6817
      pos 7009
      pos 7156
      pos 7342
      pos 7349
      pos 7428
      pos 7952
      pos 7979
      pos 8973
      pos 9021
      pos 9163
      pos 9171
      pos 9750
      pos 10712
      pos 10756
      pos 10794
      pos 10907
      pos 10911
    doc 12
      freq 109
      pos 653
      pos 805
      pos 1029
      pos 1127
      pos 1165
      pos 1194
      pos 1244
      pos 1348
      pos 1406
      pos 1453
      pos 1520
      pos 1567
      pos 1686
      pos 1733
      pos 1846
      pos 2205
      pos 2228
      pos 2499
      pos 2524
      pos 2569
      pos 2632
      pos 2721
      pos 2775
      pos 3031
      pos 3042
      pos 3079
      pos 3118
      pos 3127
      pos 3197
      pos 3239
      pos 3258
      pos 3326
      pos 3355
      pos 3400
      pos 3575
      pos 3789
      pos 3849
      pos 3874
      pos 3900
      pos 4078
      pos 4116
      pos 4169
      pos 4292
      pos 4352
      pos 4369
      pos 4542
      pos 4569
      pos 4576
      pos 4666
      pos 4800
      pos 4821
      pos 4870
      pos 5028
      pos 5051
      pos 5077
      pos 5187
      pos 5220
      pos 5230
      pos 5380
      pos 5388
      pos 5500
      pos 5543
      pos 5622
      pos 5641
      pos 5683
      pos 5713
      pos 5719
      pos 5752
      pos 5867
      pos 5945
      pos 5966
      pos 6015
      pos 6033
      pos 6068
      pos 6146
      pos 6192
      pos 6502
      pos 6589
      pos 6592
      pos 6626
      pos 6671
      pos 6859
      pos 6904
      pos 7689
      pos 7992
      pos 8033
      pos 8042
      pos 8052
      pos 8098
      pos 8246
      pos 8286
      pos 8306
      pos 8677
      pos 8689
      pos 8786
      pos 8923
      pos 8972
      pos 8993
      pos 9095
      pos 9157
      pos 9269
      pos 9301
      pos 9379
      pos 9401
      pos 9562
      pos 9606
      pos 9644
      pos 9757
      pos 9761
    doc 13
      freq 52
      pos 900
      pos 933
      pos 1032
      pos 1114
      pos 1252
      pos 1347
      pos 1366
      pos 1441
      pos 1506
      pos 1535
      pos 1762
      pos 2206
      pos 2797
      pos 2945
      pos 3248
      pos 3540
      pos 3549
      pos 3591
      pos 3788
      pos 3803
      pos 3879
      pos 3890
      pos 3919
      pos 3998
      pos 4037
      pos 4175
      pos 4426
      pos 4461
      pos 4555
      pos 4609
      pos 4652
      pos 4685
      pos 4935
      pos 5002
      pos 5105
      pos 5144
      pos 5305
      pos 5408
      pos 5503
      pos 6121
      pos 6311
      pos 6354
      pos 6425
      pos 6448
      pos 6466
      pos 6607
      pos 6612
      pos 7177
      pos 7221
      pos 7259
      pos 7372
      pos 7376
    doc 14
      freq 52
      pos 322
      pos 341
      pos 369
      pos 448
      pos 456
      pos 474
      pos 495
      pos 623
      pos 766
      pos 827
      pos 1016
      pos 1029
      pos 1045
      pos 1152
      pos 1167
      pos 1236
      pos 1366
      pos 1457
      pos 1520
      pos 1668
      pos 1681
      pos 1697
      pos 1822
      pos 1886
      pos 1910
      pos 2012
      pos 2055
      pos 2132
      pos 2174
      pos 2231
      pos 2297
      pos 2301
      pos 2304
      pos 2357
      pos 2363
      pos 2387
      pos 2451
      pos 2489
      pos 2520
      pos 2533
      pos 2584
      pos 2789
      pos 2841
      pos 2843
      pos 3557
      pos 4525
      pos 5306
      pos 5643
      pos 5687
      pos 5725
      pos 5838
      pos 5842
    doc 15
      freq 45
      pos 330
      pos 438
      pos 708
      pos 794
      pos 823
      pos 841
      pos 870
      pos 935
      pos 978
      pos 1069
      pos 1404
      pos 1479
      pos 1503
      pos 1506
      pos 1516
      pos 1650
      pos 2084
      pos 2225
      pos 2235
      pos 2330
      pos 2366
      pos 2391
      pos 2531
      pos 2694
      pos 2734
      pos 2807
      pos 2869
      pos 2895
      pos 2951
      pos 3015
      pos 3063
      pos 3073
      pos 3247
      pos 3337
      pos 3366
      pos 3390
      pos 3447
      pos 3524
      pos 3656
      pos 3722
      pos 4162
      pos 4206
      pos 4244
      pos 4357
      pos 4361
    doc 16
      freq 34
      pos 111
      pos 197
      pos 208
      pos 234
      pos 331
      pos 334
      pos 338
      pos 513
      pos 606
      pos 620
      pos 679
      pos 776
      pos 861
      pos 882
      pos 1012
      pos 1065
      pos 1124
      pos 1212
      pos 1240
      pos 1301
      pos 1357
      pos 1376
      pos 1449
      pos 1609
      pos 1909
      pos 2148
      pos 2230
      pos 2276
      pos 2471
      pos 2773
      pos 2817
      pos 2855
      pos 2968
      pos 2972
    doc 17
      freq 34
      pos 90
      pos 98
      pos 242
      pos 309
      pos 351
      pos 367
      pos 375
      pos 383
      pos 560
      pos 615
      pos 672
      pos 755
      pos 940
      pos 1127
      pos 1245
      pos 1300
      pos 1309
      pos 1317
      pos 1337
      pos 1364
      pos 1375
      pos 1386
      pos 1588
      pos 1611
      pos 1776
      pos 1812
      pos 1834
      pos 1857
      pos 1865
      pos 2497
      pos 2541
      pos 2579
      pos 2692
      pos 2696
    doc 18
      freq 39
      pos 103
      pos 200
      pos 254
      pos 311
      pos 427
      pos 529
      pos 650
      pos 688
      pos 728
      pos 738
      pos 825
      pos 832
      pos 889
      pos 963
      pos 1106
      pos 1184
      pos 1221
      pos 1231
      pos 1252
      pos 1306
      pos 1536
      pos 1547
      pos 1657
      pos 1743
      pos 1754
      pos 1763
      pos 1775
      pos 1821
      pos 1846
      pos 1870
      pos 1889
      pos 1945
      pos 1949
      pos 1955
      pos 2285
      pos 2329
      pos 2367
      pos 2480
      pos 2484
    skipList 
      level 0
        skipDoc 7
        skipDocFP 2258438
        impacts 
          impact 
            freq 29
            norm 100
          impact 
            freq 31
            norm 104
          impact 
            freq 45
            norm 107
          impact 
            freq 54
            norm 108
          impact 
            freq 99
            norm 113
        impactsEnd 
        skipDoc 15
        skipDocFP 2264806
        impacts 
          impact 
            freq 22
            norm 95
          impact 
            freq 45
            norm 104
          impact 
            freq 52
            norm 107
          impact 
            freq 109
            norm 113
          impact 
            freq 211
            norm 116
        impactsEnd 
  term the
    doc 0
      freq 836
      pos 41
      pos 54
      pos 58
      pos 66
      pos 84
      pos 95
      pos 107
      pos 117
      pos 142
      pos 193
      pos 203
      pos 207
      pos 232
      pos 244
      pos 252
      pos 257
      pos 261
      pos 277
      pos 309
      pos 342
      pos 348
      pos 362
      pos 376
      pos 415
      pos 419
      pos 422
      pos 451
      pos 456
      pos 473
      pos 508
      pos 540
      pos 576
      pos 585
      pos 604
      pos 638
      pos 671
      pos 708
      pos 741
      pos 757
      pos 764
      pos 782
      pos 801
      pos 833
      pos 848
      pos 856
      pos 888
      pos 900
      pos 908
      pos 911
      pos 920
      pos 951
      pos 1130
      pos 1181
      pos 1211
      pos 1227
      pos 1254
      pos 1285
      pos 1289
      pos 1370
      pos 1378
      pos 1438
      pos 1462
      pos 1470
      pos 1502
      pos 1512
      pos 1517
      pos 1529
      pos 1532
      pos 1561
      pos 1567
      pos 1641
      pos 1670
      pos 1727
      pos 1959
      pos 2038
      pos 2073
      pos 2114
      pos 2119
      pos 2122
      pos 2127
      pos 2140
      pos 2147
      pos 2151
      pos 2166
      pos 2169
      pos 2174
      pos 2182
      pos 2186
      pos 2197
      pos 2208
      pos 2214
      pos 2218
      pos 2235
      pos 2260
      pos 2298
      pos 2302
      pos 2345
      pos 2356
      pos 2394
      pos 2407
      pos 2412
      pos 2416
      pos 2443
      pos 2499
      pos 2567
      pos 2570
      pos 2622
      pos 2630
      pos 2640
      pos 2684
      pos 2690
      pos 2732
      pos 2743
      pos 2753
      pos 2782
      pos 2824
      pos 2867
      pos 2885
      pos 2890
      pos 2961
      pos 2995
      pos 3024
      pos 3045
      pos 3062
      pos 3071
      pos 3093
      pos 3097
      pos 3119
      pos 3197
      pos 3207
      pos 3216
      pos 3225
      pos 3253
      pos 3256
      pos 3259
      pos 3277
      pos 3285
      pos 3305
      pos 3314
      pos 3320
      pos 3327
      pos 3330
      pos 3362
      pos 3365
      pos 3487
      pos 3491
      pos 3496
      pos 3504
      pos 3531
      pos 3563
      pos 3571
      pos 3574
      pos 3582
      pos 3621
      pos 3704
      pos 3727
      pos 3735
      pos 3747
      pos 3753
      pos 3761
      pos 3764
      pos 3781
      pos 3784
      pos 3791
      pos 3794
      pos 3816
      pos 3821
      pos 3831
      pos 3838
      pos 3841
      pos 3845
      pos 3858
      pos 3890
      pos 3912
      pos 3933
      pos 3963
      pos 3982
      pos 4051
      pos 4055
      pos 4072
      pos 4137
      pos 4216
      pos 4239
      pos 4247
      pos 4255
      pos 4258
      pos 4261
      pos 4273
      pos 4293
      pos 4296
      pos 4303
      pos 4306
      pos 4316
      pos 4321
      pos 4331
      pos 4338
      pos 4341
      pos 4345
      pos 4358
      pos 4390
      pos 4424
      pos 4433
      pos 4448
      pos 4466
      pos 4534
      pos 4538
      pos 4567
      pos 4571
      pos 4593
      pos 4597
      pos 4620
      pos 4625
      pos 4633
      pos 4644
      pos 4664
      pos 4744
      pos 4764
      pos 4786
      pos 4843
      pos 4873
      pos 4876
      pos 4881
      pos 4894
      pos 4910
      pos 4926
      pos 4930
      pos 4936
      pos 4940
      pos 4950
      pos 4974
      pos 4978
      pos 4980
      pos 4989
      pos 5010
      pos 5055
      pos 5064
      pos 5075
      pos 5088
      pos 5094
      pos 5108
      pos 5115
      pos 5118
      pos 5127
      pos 5263
      pos 5291
      pos 5297
      pos 5299
      pos 5303
      pos 5311
      pos 5320
      pos 5326
      pos 5331
      pos 5335
      pos 5341
      pos 5346
      pos 5350
      pos 5363
      pos 5374
      pos 5381
      pos 5395
      pos 5418
      pos 5536
      pos 5549
      pos 5600
      pos 5605
      pos 5633
      pos 5637
      pos 5655
      pos 5662
      pos 5667
      pos 5680
      pos 5691
      pos 5708
      pos 5739
      pos 5742
      pos 5747
      pos 5750
      pos 5757
      pos 5760
      pos 5776
      pos 5848
      pos 5855
      pos 5862
      pos 5868
      pos 5873
      pos 5880
      pos 5893
      pos 5925
      pos 5978
      pos 6005
      pos 6030
      pos 6057
      pos 6098
      pos 6107
      pos 6144
      pos 6155
      pos 6160
      pos 6166
      pos 6222
      pos 6228
      pos 6257
      pos 6390
      pos 6410
      pos 6451
      pos 6477
      pos 6481
      pos 6516
      pos 6520
      pos 6528
      pos 6533
      pos 6562
      pos 6568
      pos 6582
      pos 6588
      pos 6597
      pos 6601
      pos 6634
      pos 6640
      pos 6669
      pos 6672
      pos 6675
      pos 6680
      pos 6688
      pos 6695
      pos 6702
      pos 6706
      pos 6729
      pos 6732
      pos 6753
      pos 6761
      pos 6765
      pos 6795
      pos 6799
      pos 6808
      pos 6864
      pos 6871
      pos 6916
      pos 6956
      pos 6963
      pos 7046
      pos 7069
      pos 7129
      pos 7138
      pos 7181
      pos 7295
      pos 7332
      pos 7360
      pos 7395
      pos 7428
      pos 7456
      pos 7490
      pos 7525
      pos 7531
      pos 7588
      pos 7642
      pos 7859
      pos 7907
      pos 7938
      pos 7975
      pos 8016
      pos 8055
      pos 8096
      pos 8150
      pos 8187
      pos 8197
      pos 8221
      pos 8225
      pos 8237
      pos 8253
      pos 8374
      pos 8449
      pos 8471
      pos 8517
      pos 8533
      pos 8575
      pos 8590
      pos 8645
      pos 8690
      pos 8735
      pos 8777
      pos 8794
      pos 8836
      pos 8938
      pos 8955
      pos 8958
      pos 8984
      pos 8987
      pos 9015
      pos 9019
      pos 9026
      pos 9029
      pos 9033
      pos 9060
      pos 9064
      pos 9105
      pos 9108
      pos 9129
      pos 9133
      pos 9155
      pos 9163
      pos 9187
      pos 9204
      pos 9210
      pos 9219
      pos 9259
      pos 9276
      pos 9301
      pos 9307
      pos 9330
      pos 9335
      pos 9345
      pos 9350
      pos 9357
      pos 9367
      pos 9373
      pos 9380
      pos 9411
      pos 9510
      pos 9523
      pos 9549
      pos 9553
      pos 9559
      pos 9566
      pos 9610
      pos 9699
      pos 9721
      pos 9746
      pos 9772
      pos 9774
      pos 9782
      pos 9785
      pos 9790
      pos 9796
      pos 9803
      pos 9835
      pos 9934
      pos 9938
      pos 9942
      pos 9961
      pos 9982
      pos 10082
      pos 10097
      pos 10115
      pos 10125
      pos 10143
      pos 10176
      pos 10180
      pos 10186
      pos 10205
      pos 10219
      pos 10250
      pos 10259
      pos 10277
      pos 10280
      pos 10289
      pos 10294
      pos 10302
      pos 10311
      pos 10315
      pos 10323
      pos 10328
      pos 10331
      pos 10335
      pos 10339
      pos 10346
      pos 10368
      pos 10398
      pos 10403
      pos 10406
      pos 10414
      pos 10425
      pos 10430
      pos 10433
      pos 10436
      pos 10440
      pos 10446
      pos 10452
      pos 10477
      pos 10482
      pos 10491
      pos 10516
      pos 10525
      pos 10548
      pos 10566
      pos 10570
      pos 10576
      pos 10606
      pos 10631
      pos 10634
      pos 10648
      pos 10650
      pos 10654
      pos 10661
      pos 10666
      pos 10670
      pos 10681
      pos 10684
      pos 10693
      pos 10698
      pos 10729
      pos 10733
      pos 10742
      pos 10755
      pos 10765
      pos 10771
      pos 10773
      pos 10782
      pos 10822
      pos 10834
      pos 10858
      pos 10896
      pos 10951
      pos 10960
      pos 10978
      pos 11080
      pos 11113
      pos 11130
      pos 11138
      pos 11141
      pos 11158
      pos 11161
      pos 11167
      pos 11170
      pos 11180
      pos 11185
      pos 11195
      pos 11202
      pos 11205
      pos 11209
      pos 11222
      pos 11270
      pos 11287
      pos 11290
      pos 11321
      pos 11328
      pos 11336
      pos 11339
      pos 11360
      pos 11374
      pos 11395
      pos 11412
      pos 11422
      pos 11442
      pos 11463
      pos 11467
      pos 11474
      pos 11507
      pos 11512
      pos 11521
      pos 11542
      pos 11551
      pos 11570
      pos 11576
      pos 11585
      pos 11604
      pos 11629
      pos 11680
      pos 11687
      pos 11691
      pos 11699
      pos 11720
      pos 11750
      pos 11829
      pos 11853
      pos 11907
      pos 11931
      pos 11953
      pos 11975
      pos 11981
      pos 11993
      pos 12004
      pos 12014
      pos 12025
      pos 12029
      pos 12057
      pos 12062
      pos 12089
      pos 12135
      pos 12141
      pos 12143
      pos 12150
      pos 12184
      pos 12204
      pos 12226
      pos 12245
      pos 12268
      pos 12275
      pos 12280
      pos 12322
      pos 12345
      pos 12405
      pos 12423
      pos 12448
      pos 12486
      pos 12512
      pos 12542
      pos 12548
      pos 12551
      pos 12555
      pos 12586
      pos 12612
      pos 12660
      pos 12690
      pos 12699
      pos 12702
      pos 12705
      pos 12709
      pos 12714
      pos 12736
      pos 12800
      pos 12805
      pos 12808
      pos 12841
      pos 12853
      pos 12857
      pos 12863
      pos 12876
      pos 12880
      pos 12945
      pos 12968
      pos 12979
      pos 13009
      pos 13018
      pos 13053
      pos 13058
      pos 13062
      pos 13094
      pos 13105
      pos 13110
      pos 13113
      pos 13116
      pos 13125
      pos 13128
      pos 13130
      pos 13134
      pos 13208
      pos 13215
      pos 13218
      pos 13227
      pos 13230
      pos 13232
      pos 13236
      pos 13301
      pos 13308
      pos 13319
      pos 13322
      pos 13365
      pos 13381
      pos 13395
      pos 13424
      pos 13432
      pos 13435
      pos 13444
      pos 13447
      pos 13449
      pos 13453
      pos 13518
      pos 13521
      pos 13530
      pos 13533
      pos 13547
      pos 13551
      pos 13617
      pos 13622
      pos 13625
      pos 13634
      pos 13637
      pos 13639
      pos 13643
      pos 13712
      pos 13715
      pos 13724
      pos 13727
      pos 13741
      pos 13745
      pos 13814
      pos 13818
      pos 13881
      pos 13884
      pos 13886
      pos 13890
      pos 13970
      pos 13983
      pos 13989
      pos 13992
      pos 13999
      pos 14007
      pos 14010
      pos 14014
      pos 14017
      pos 14026
      pos 14030
      pos 14102
      pos 14107
      pos 14116
      pos 14125
      pos 14144
      pos 14151
      pos 14155
      pos 14159
      pos 14221
      pos 14226
      pos 14229
      pos 14232
      pos 14235
      pos 14238
      pos 14242
      pos 14272
      pos 14278
      pos 14282
      pos 14285
      pos 14288
      pos 14291
      pos 14294
      pos 14298
      pos 14301
      pos 14310
      pos 14313
      pos 14330
      pos 14333
      pos 14336
      pos 14340
      pos 14346
      pos 14349
      pos 14365
      pos 14390
      pos 14397
      pos 14413
      pos 14455
      pos 14465
      pos 14479
      pos 14489
      pos 14515
      pos 14525
      pos 14555
      pos 14563
      pos 14579
      pos 14621
      pos 14631
      pos 14645
      pos 14655
      pos 14681
      pos 14691
      pos 14705
      pos 14715
      pos 14729
      pos 14739
      pos 14781
      pos 15462
      pos 15530
      pos 15576
      pos 15611
      pos 15657
      pos 15681
      pos 15709
      pos 15716
      pos 15751
      pos 15781
      pos 15788
      pos 15809
      pos 15816
      pos 15825
      pos 15857
      pos 15876
      pos 15886
      pos 15903
      pos 16012
      pos 16027
      pos 16048
      pos 16052
      pos 16057
      pos 16064
      pos 16083
      pos 16139
      pos 16198
      pos 16209
      pos 16225
      pos 16292
      pos 16297
      pos 16306
      pos 16349
      pos 16352
      pos 16389
      pos 16428
      pos 16444
      pos 16458
      pos 16502
      pos 16534
      pos 16554
      pos 16566
      pos 16588
      pos 16594
      pos 16625
      pos 16644
      pos 16664
      pos 16687
      pos 16695
      pos 16700
      pos 16722
      pos 16728
      pos 16739
      pos 16759
      pos 16779
      pos 16793
      pos 16831
      pos 16862
      pos 16902
      pos 16906
      pos 16928
      pos 16986
      pos 17006
      pos 17228
      pos 17237
      pos 17252
      pos 17261
      pos 17273
      pos 17275
      pos 17286
      pos 17290
      pos 17309
      pos 17312
      pos 17334
      pos 17340
      pos 17359
      pos 17364
      pos 17371
      pos 17404
      pos 17428
      pos 17441
      pos 17455
      pos 17472
      pos 17482
      pos 17517
      pos 17520
      pos 17529
      pos 17536
    doc 1
      freq 725
      pos 40
      pos 58
      pos 71
      pos 75
      pos 83
      pos 101
      pos 127
      pos 174
      pos 223
      pos 249
      pos 255
      pos 267
      pos 326
      pos 337
      pos 478
      pos 481
      pos 495
      pos 499
      pos 503
      pos 505
      pos 510
      pos 514
      pos 519
      pos 525
      pos 533
      pos 556
      pos 582
      pos 591
      pos 615
      pos 619
      pos 626
      pos 683
      pos 687
      pos 691
      pos 712
      pos 719
      pos 730
      pos 733
      pos 748
      pos 799
      pos 803
      pos 819
      pos 826
      pos 843
      pos 847
      pos 856
      pos 865
      pos 868
      pos 883
      pos 897
      pos 924
      pos 950
      pos 955
      pos 965
      pos 994
      pos 999
      pos 1009
      pos 1113
      pos 1123
      pos 1129
      pos 1158
      pos 1187
      pos 1243
      pos 1252
      pos 1259
      pos 1310
      pos 1321
      pos 1329
      pos 1335
      pos 1355
      pos 1382
      pos 1395
      pos 1406
      pos 1423
      pos 1453
      pos 1459
      pos 1470
      pos 1489
      pos 1493
      pos 1497
      pos 1501
      pos 1505
      pos 1512
      pos 1517
      pos 1521
      pos 1524
      pos 1528
      pos 1531
      pos 1539
      pos 1548
      pos 1553
      pos 1557
      pos 1560
      pos 1570
      pos 1593
      pos 1596
      pos 1600
      pos 1605
      pos 1609
      pos 1625
      pos 1628
      pos 1632
      pos 1636
      pos 1651
      pos 1654
      pos 1659
      pos 1680
      pos 1696
      pos 1710
      pos 1719
      pos 1723
      pos 1726
      pos 1738
      pos 1744
      pos 1751
      pos 1754
      pos 1764
      pos 1778
      pos 1790
      pos 1794
      pos 1814
      pos 1825
      pos 1838
      pos 1875
      pos 1902
      pos 1910
      pos 1924
      pos 1929
      pos 1932
      pos 1955
      pos 1958
      pos 1994
      pos 2001
      pos 2009
      pos 2014
      pos 2017
      pos 2020
      pos 2026
      pos 2035
      pos 2045
      pos 2052
      pos 2059
      pos 2067
      pos 2075
      pos 2105
      pos 2112
      pos 2115
      pos 2118
      pos 2121
      pos 2129
      pos 2168
      pos 2176
      pos 2183
      pos 2232
      pos 2243
      pos 2259
      pos 2279
      pos 2313
      pos 2336
      pos 2387
      pos 2391
      pos 2406
      pos 2412
      pos 2439
      pos 2513
      pos 2536
      pos 2543
      pos 2570
      pos 2584
      pos 2589
      pos 2607
      pos 2646
      pos 2649
      pos 2679
      pos 2685
      pos 2702
      pos 2740
      pos 2749
      pos 2753
      pos 2758
      pos 2786
      pos 2794
      pos 2796
      pos 2805
      pos 2809
      pos 2816
      pos 2835
      pos 2838
      pos 2850
      pos 2855
      pos 2861
      pos 2884
      pos 2892
      pos 2897
      pos 2914
      pos 2926
      pos 2933
      pos 2939
      pos 2951
      pos 2960
      pos 2963
      pos 2975
      pos 2984
      pos 2995
      pos 2999
      pos 3003
      pos 3006
      pos 3017
      pos 3023
      pos 3028
      pos 3040
      pos 3078
      pos 3088
      pos 3098
      pos 3101
      pos 3106
      pos 3115
      pos 3118
      pos 3123
      pos 3126
      pos 3129
      pos 3134
      pos 3174
      pos 3181
      pos 3184
      pos 3189
      pos 3192
      pos 3240
      pos 3244
      pos 3288
      pos 3300
      pos 3306
      pos 3312
      pos 3317
      pos 3338
      pos 3349
      pos 3353
      pos 3383
      pos 3400
      pos 3433
      pos 3437
      pos 3443
      pos 3455
      pos 3475
      pos 3501
      pos 3507
      pos 3513
      pos 3517
      pos 3520
      pos 3526
      pos 3530
      pos 3533
      pos 3538
      pos 3543
      pos 3548
      pos 3551
      pos 3560
      pos 3563
      pos 3576
      pos 3579
      pos 3589
      pos 3596
      pos 3618
      pos 3629
      pos 3707
      pos 3716
      pos 3730
      pos 3741
      pos 3745
      pos 3748
      pos 3759
      pos 3763
      pos 3766
      pos 3769
      pos 3777
      pos 3799
      pos 3804
      pos 3809
      pos 3813
      pos 3819
      pos 3822
      pos 3841
      pos 3866
      pos 3879
      pos 3884
      pos 3888
      pos 3891
      pos 3921
      pos 3928
      pos 3942
      pos 3956
      pos 3975
      pos 3978
      pos 3984
      pos 3987
      pos 3990
      pos 4063
      pos 4119
      pos 4168
      pos 4195
      pos 4207
      pos 4211
      pos 4220
      pos 4229
      pos 4233
      pos 4252
      pos 4258
      pos 4276
      pos 4290
      pos 4297
      pos 4304
      pos 4310
      pos 4332
      pos 4335
      pos 4360
      pos 4368
      pos 4372
      pos 4381
      pos 4385
      pos 4390
      pos 4394
      pos 4401
      pos 4407
      pos 4424
      pos 4439
      pos 4443
      pos 4446
      pos 4449
      pos 4472
      pos 4512
      pos 4528
      pos 4553
      pos 4556
      pos 4562
      pos 4572
      pos 4575
      pos 4580
      pos 4587
      pos 4593
      pos 4597
      pos 4605
      pos 4615
      pos 4618
      pos 4623
      pos 4626
      pos 4645
      pos 4660
      pos 4668
      pos 4675
      pos 4679
      pos 4701
      pos 4719
      pos 4730
      pos 4762
      pos 4769
      pos 4784
      pos 4789
      pos 4797
      pos 4800
      pos 4813
      pos 4826
      pos 4835
      pos 4839
      pos 4847
      pos 4851
      pos 4855
      pos 4862
      pos 4892
      pos 4900
      pos 4906
      pos 4910
      pos 4921
      pos 4924
      pos 4941
      pos 4956
      pos 4967
      pos 4978
      pos 4984
      pos 4992
      pos 4997
      pos 5028
      pos 5050
      pos 5056
      pos 5059
      pos 5108
      pos 5120
      pos 5126
      pos 5129
      pos 5132
      pos 5144
      pos 5174
      pos 5179
      pos 5182
      pos 5206
      pos 5210
      pos 5216
      pos 5221
      pos 5225
      pos 5229
      pos 5303
      pos 5330
      pos 5341
      pos 5348
      pos 5358
      pos 5373
      pos 5378
      pos 5395
      pos 5415
      pos 5421
      pos 5429
      pos 5435
      pos 5443
      pos 5448
      pos 5453
      pos 5460
      pos 5488
      pos 5497
      pos 5503
      pos 5512
      pos 5520
      pos 5529
      pos 5535
      pos 5543
      pos 5552
      pos 5560
      pos 5567
      pos 5575
      pos 5615
      pos 5621
      pos 5624
      pos 5637
      pos 5645
      pos 5651
      pos 5655
      pos 5660
      pos 5669
      pos 5672
      pos 5678
      pos 5762
      pos 5772
      pos 5777
      pos 5792
      pos 5798
      pos 5802
      pos 5807
      pos 5818
      pos 5826
      pos 5829
      pos 5836
      pos 5843
      pos 5845
      pos 5855
      pos 5860
      pos 5868
      pos 5872
      pos 5880
      pos 5884
      pos 5895
      pos 5907
      pos 5912
      pos 5921
      pos 5926
      pos 5929
      pos 5934
      pos 5941
      pos 5949
      pos 5963
      pos 5986
      pos 5989
      pos 5995
      pos 5998
      pos 6001
      pos 6009
      pos 6076
      pos 6096
      pos 6102
      pos 6105
      pos 6109
      pos 6118
      pos 6145
      pos 6151
      pos 6159
      pos 6167
      pos 6174
      pos 6237
      pos 6240
      pos 6253
      pos 6276
      pos 6281
      pos 6293
      pos 6298
      pos 6351
      pos 6376
      pos 6391
      pos 6399
      pos 6419
      pos 6422
      pos 6448
      pos 6463
      pos 6471
      pos 6487
      pos 6490
      pos 6503
      pos 6515
      pos 6522
      pos 6529
      pos 6545
      pos 6553
      pos 6562
      pos 6569
      pos 6572
      pos 6586
      pos 6593
      pos 6602
      pos 6609
      pos 6612
      pos 6619
      pos 6634
      pos 6642
      pos 6651
      pos 6660
      pos 6674
      pos 6677
      pos 6684
      pos 6698
      pos 6706
      pos 6713
      pos 6726
      pos 6741
      pos 6746
      pos 6766
      pos 6780
      pos 6791
      pos 6799
      pos 6812
      pos 6836
      pos 6850
      pos 6860
      pos 6865
      pos 6876
      pos 6917
      pos 6929
      pos 6949
      pos 6954
      pos 6976
      pos 6980
      pos 7000
      pos 7003
      pos 7021
      pos 7028
      pos 7046
      pos 7050
      pos 7054
      pos 7081
      pos 7087
      pos 7098
      pos 7103
      pos 7108
      pos 7115
      pos 7143
      pos 7153
      pos 7159
      pos 7168
      pos 7175
      pos 7184
      pos 7205
      pos 7211
      pos 7219
      pos 7228
      pos 7235
      pos 7243
      pos 7250
      pos 7258
      pos 7285
      pos 7295
      pos 7301
      pos 7310
      pos 7340
      pos 7359
      pos 7366
      pos 7369
      pos 7372
      pos 7377
      pos 7385
      pos 7401
      pos 7408
      pos 7420
      pos 7425
      pos 7436
      pos 7443
      pos 7453
      pos 7475
      pos 7479
      pos 7489
      pos 7514
      pos 7519
      pos 7526
      pos 7537
      pos 7540
      pos 7546
      pos 7549
      pos 7555
      pos 7586
      pos 7590
      pos 7610
      pos 7622
      pos 7666
      pos 7675
      pos 7688
      pos 7694
      pos 7705
      pos 7731
      pos 7735
      pos 7770
      pos 7820
      pos 7913
      pos 7920
      pos 7933
      pos 7945
      pos 7971
      pos 7976
      pos 7981
      pos 7985
      pos 7995
      pos 7998
      pos 8001
      pos 8028
      pos 8053
      pos 8062
      pos 8072
      pos 8099
      pos 8117
      pos 8156
      pos 8160
      pos 8166
      pos 8170
      pos 8176
      pos 8199
      pos 8202
      pos 8210
      pos 8250
      pos 8264
      pos 8267
      pos 8270
      pos 8279
      pos 8282
      pos 8286
      pos 8294
      pos 8298
      pos 8304
      pos 8307
      pos 8314
      pos 8318
      pos 8321
      pos 8325
      pos 8328
      pos 8336
      pos 8339
      pos 8346
      pos 8349
      pos 8356
      pos 8362
      pos 8365
      pos 8381
      pos 8385
      pos 8393
      pos 8398
      pos 8412
      pos 8429
      pos 8494
      pos 8501
      pos 8542
      pos 8549
      pos 8596
      pos 8601
      pos 8608
      pos 8616
      pos 8622
      pos 8656
      pos 8661
      pos 8669
      pos 8679
      pos 8689
      pos 8694
      pos 8739
      pos 8752
      pos 8771
      pos 8779
      pos 8785
      pos 8791
      pos 8795
      pos 8803
      pos 8811
      pos 8820
      pos 8865
      pos 8872
      pos 8877
      pos 9142
      pos 9460
      pos 9478
      pos 9609
      pos 9618
      pos 9633
      pos 9642
      pos 9654
      pos 9656
      pos 9667
      pos 9671
      pos 9690
      pos 9693
      pos 9715
      pos 9721
      pos 9740
      pos 9745
      pos 9752
      pos 9785
      pos 9809
      pos 9822
      pos 9836
      pos 9853
      pos 9863
      pos 9898
      pos 9901
      pos 9910
      pos 9917
    doc 2
      freq 348
      pos 17
      pos 31
      pos 54
      pos 60
      pos 70
      pos 89
      pos 101
      pos 109
      pos 185
      pos 206
      pos 214
      pos 219
      pos 240
      pos 245
      pos 254
      pos 258
      pos 264
      pos 268
      pos 274
      pos 285
      pos 297
      pos 306
      pos 320
      pos 327
      pos 341
      pos 348
      pos 369
      pos 413
      pos 417
      pos 421
      pos 437
      pos 444
      pos 449
      pos 457
      pos 467
      pos 490
      pos 507
      pos 514
      pos 551
      pos 565
      pos 582
      pos 608
      pos 644
      pos 650
      pos 657
      pos 666
      pos 670
      pos 676
      pos 684
      pos 689
      pos 721
      pos 746
      pos 751
      pos 780
      pos 831
      pos 846
      pos 866
      pos 889
      pos 899
      pos 903
      pos 918
      pos 943
      pos 966
      pos 1008
      pos 1015
      pos 1023
      pos 1041
      pos 1062
      pos 1084
      pos 1122
      pos 1139
      pos 1168
      pos 1244
      pos 1254
      pos 1281
      pos 1299
      pos 1304
      pos 1417
      pos 1420
      pos 1445
      pos 1449
      pos 1452
      pos 1492
      pos 1521
      pos 1541
      pos 1572
      pos 1635
      pos 1647
      pos 1661
      pos 1669
      pos 1681
      pos 1685
      pos 1703
      pos 1725
      pos 1735
      pos 1742
      pos 1755
      pos 1766
      pos 1809
      pos 1827
      pos 1831
      pos 1836
      pos 1854
      pos 1912
      pos 1922
      pos 1938
      pos 1950
      pos 2035
      pos 2052
      pos 2058
      pos 2064
      pos 2069
      pos 2073
      pos 2087
      pos 2109
      pos 2124
      pos 2130
      pos 2156
      pos 2165
      pos 2194
      pos 2264
      pos 2314
      pos 2857
      pos 3218
      pos 3254
      pos 3417
      pos 3453
      pos 3506
      pos 3515
      pos 3523
      pos 3529
      pos 3540
      pos 3544
      pos 3551
      pos 3555
      pos 3575
      pos 3578
      pos 3582
      pos 3611
      pos 3620
      pos 3639
      pos 3643
      pos 3649
      pos 3656
      pos 3672
      pos 3680
      pos 3688
      pos 3706
      pos 3717
      pos 3738
      pos 3741
      pos 3748
      pos 3769
      pos 3775
      pos 3778
      pos 3784
      pos 3789
      pos 3793
      pos 3798
      pos 3802
      pos 3807
      pos 3816
      pos 3820
      pos 3833
      pos 3849
      pos 3879
      pos 3898
      pos 3911
      pos 3927
      pos 3950
      pos 3971
      pos 3983
      pos 3987
      pos 3997
      pos 4004
      pos 4015
      pos 4030
      pos 4041
      pos 4044
      pos 4053
      pos 4071
      pos 4078
      pos 4081
      pos 4084
      pos 4112
      pos 4134
      pos 4200
      pos 4217
      pos 4223
      pos 4230
      pos 4234
      pos 4241
      pos 4246
      pos 4262
      pos 4266
      pos 4284
      pos 4290
      pos 4298
      pos 4309
      pos 4313
      pos 4318
      pos 4329
      pos 4344
      pos 4356
      pos 4360
      pos 4374
      pos 4397
      pos 4410
      pos 4428
      pos 4445
      pos 4450
      pos 4453
      pos 4469
      pos 4486
      pos 4490
      pos 4502
      pos 4524
      pos 4531
      pos 4534
      pos 4558
      pos 4562
      pos 4574
      pos 4579
      pos 4584
      pos 4591
      pos 4605
      pos 4608
      pos 4634
      pos 4652
      pos 4684
      pos 4693
      pos 4704
      pos 4734
      pos 4739
      pos 4763
      pos 4774
      pos 4795
      pos 4798
      pos 4801
      pos 4812
      pos 4821
      pos 4839
      pos 4880
      pos 4890
      pos 4909
      pos 4921
      pos 4963
      pos 4977
      pos 4995
      pos 5010
      pos 5031
      pos 5042
      pos 5104
      pos 5113
      pos 5119
      pos 5142
      pos 5148
      pos 5160
      pos 5181
      pos 5184
      pos 5188
      pos 5214
      pos 5228
      pos 5241
      pos 5252
      pos 5262
      pos 5269
      pos 5277
      pos 5286
      pos 5313
      pos 5332
      pos 5343
      pos 5351
      pos 5381
      pos 5439
      pos 5453
      pos 5473
      pos 5483
      pos 5492
      pos 5511
      pos 5519
      pos 5528
      pos 5534
      pos 5593
      pos 5604
      pos 5616
      pos 5704
      pos 5755
      pos 5775
      pos 5788
      pos 5831
      pos 5837
      pos 5852
      pos 5861
      pos 5865
      pos 5873
      pos 5881
      pos 5888
      pos 5899
      pos 5903
      pos 5918
      pos 5924
      pos 5944
      pos 5982
      pos 5987
      pos 6018
      pos 6074
      pos 6082
      pos 6086
      pos 6090
      pos 6102
      pos 6111
      pos 6119
      pos 6137
      pos 6175
      pos 6189
      pos 6196
      pos 6250
      pos 6270
      pos 6282
      pos 6297
      pos 6312
      pos 6343
      pos 6406
      pos 6415
      pos 6430
      pos 6439
      pos 6451
      pos 6453
      pos 6464
      pos 6468
      pos 6487
      pos 6490
      pos 6512
      pos 6518
      pos 6537
      pos 6542
      pos 6549
      pos 6582
      pos 6606
      pos 6619
      pos 6633
      pos 6650
      pos 6660
      pos 6695
      pos 6698
      pos 6707
      pos 6714
    doc 3
      freq 434
      pos 52
      pos 65
      pos 69
      pos 77
      pos 95
      pos 134
      pos 146
      pos 233
      pos 258
      pos 369
      pos 401
      pos 408
      pos 419
      pos 430
      pos 436
      pos 443
      pos 454
      pos 484
      pos 490
      pos 520
      pos 523
      pos 552
      pos 557
      pos 567
      pos 643
      pos 656
      pos 667
      pos 673
      pos 682
      pos 699
      pos 715
      pos 718
      pos 769
      pos 779
      pos 785
      pos 808
      pos 825
      pos 838
      pos 848
      pos 853
      pos 855
      pos 860
      pos 867
      pos 870
      pos 913
      pos 921
      pos 928
      pos 952
      pos 956
      pos 960
      pos 964
      pos 966
      pos 979
      pos 986
      pos 1018
      pos 1027
      pos 1047
      pos 1050
      pos 1055
      pos 1059
      pos 1071
      pos 1077
      pos 1093
      pos 1100
      pos 1107
      pos 1116
      pos 1148
      pos 1154
      pos 1157
      pos 1164
      pos 1181
      pos 1200
      pos 1206
      pos 1233
      pos 1266
      pos 1291
      pos 1311
      pos 1318
      pos 1324
      pos 1353
      pos 1361
      pos 1369
      pos 1374
      pos 1380
      pos 1387
      pos 1390
      pos 1394
      pos 1396
      pos 1401
      pos 1405
      pos 1409
      pos 1415
      pos 1434
      pos 1438
      pos 1456
      pos 1490
      pos 1496
      pos 1501
      pos 1514
      pos 1519
      pos 1537
      pos 1552
      pos 1557
      pos 1574
      pos 1583
      pos 1595
      pos 1606
      pos 1610
      pos 1621
      pos 1637
      pos 1657
      pos 1676
      pos 1679
      pos 1698
      pos 1706
      pos 1722
      pos 1728
      pos 1731
      pos 1747
      pos 1761
      pos 1768
      pos 1787
      pos 1793
      pos 1798
      pos 1816
      pos 1846
      pos 1854
      pos 1865
      pos 1871
      pos 1876
      pos 1881
      pos 1892
      pos 1904
      pos 1955
      pos 1958
      pos 1964
      pos 1967
      pos 1970
      pos 1978
      pos 1987
      pos 2004
      pos 2025
      pos 2042
      pos 2050
      pos 2059
      pos 2064
      pos 2068
      pos 2072
      pos 2082
      pos 2089
      pos 2094
      pos 2129
      pos 2136
      pos 2140
      pos 2149
      pos 2157
      pos 2165
      pos 2168
      pos 2172
      pos 2183
      pos 2192
      pos 2195
      pos 2202
      pos 2205
      pos 2209
      pos 2213
      pos 2224
      pos 2232
      pos 2234
      pos 2240
      pos 2256
      pos 2269
      pos 2282
      pos 2292
      pos 2303
      pos 2310
      pos 2315
      pos 2331
      pos 2338
      pos 2350
      pos 2358
      pos 2363
      pos 2374
      pos 2379
      pos 2384
      pos 2396
      pos 2415
      pos 2418
      pos 2437
      pos 2446
      pos 2451
      pos 2464
      pos 2469
      pos 2480
      pos 2498
      pos 2508
      pos 2513
      pos 2517
      pos 2524
      pos 2527
      pos 2530
      pos 2535
      pos 2550
      pos 2560
      pos 2565
      pos 2568
      pos 2579
      pos 2583
      pos 2592
      pos 2595
      pos 2599
      pos 2605
      pos 2620
      pos 2625
      pos 2655
      pos 2661
      pos 2665
      pos 2669
      pos 2673
      pos 2678
      pos 2702
      pos 2709
      pos 2713
      pos 2719
      pos 2725
      pos 2737
      pos 2756
      pos 2759
      pos 2775
      pos 2779
      pos 2788
      pos 2835
      pos 2839
      pos 2851
      pos 2854
      pos 2859
      pos 2865
      pos 2881
      pos 2884
      pos 2890
      pos 2894
      pos 2897
      pos 2902
      pos 2923
      pos 2933
      pos 2937
      pos 2949
      pos 2953
      pos 2972
      pos 2990
      pos 2998
      pos 3060
      pos 3071
      pos 3077
      pos 3080
      pos 3082
      pos 3115
      pos 3130
      pos 3136
      pos 3152
      pos 3162
      pos 3173
      pos 3176
      pos 3187
      pos 3217
      pos 3223
      pos 3261
      pos 3264
      pos 3274
      pos 3287
      pos 3294
      pos 3336
      pos 3339
      pos 3344
      pos 3364
      pos 3368
      pos 3375
      pos 3384
      pos 3394
      pos 3420
      pos 3425
      pos 3442
      pos 3473
      pos 3476
      pos 3514
      pos 3516
      pos 3541
      pos 3564
      pos 3571
      pos 3579
      pos 3598
      pos 3624
      pos 3675
      pos 3678
      pos 3691
      pos 3694
      pos 3717
      pos 3734
      pos 3737
      pos 3743
      pos 3754
      pos 3764
      pos 3772
      pos 3785
      pos 3790
      pos 3797
      pos 3803
      pos 3813
      pos 3817
      pos 3821
      pos 3829
      pos 3834
      pos 3838
      pos 3842
      pos 3846
      pos 3852
      pos 3857
      pos 3863
      pos 3867
      pos 3876
      pos 3889
      pos 3893
      pos 3903
      pos 3921
      pos 3927
      pos 3931
      pos 3951
      pos 3972
      pos 3988
      pos 4000
      pos 4020
      pos 4026
      pos 4035
      pos 4040
      pos 4053
      pos 4060
      pos 4068
      pos 4077
      pos 4087
      pos 4097
      pos 4100
      pos 4109
      pos 4112
      pos 4115
      pos 4140
      pos 4150
      pos 4169
      pos 4178
      pos 4217
      pos 4233
      pos 4237
      pos 4251
      pos 4262
      pos 4273
      pos 4276
      pos 4285
      pos 4375
      pos 5018
      pos 5024
      pos 5036
      pos 5119
      pos 5148
      pos 5153
      pos 5157
      pos 5185
      pos 5227
      pos 5238
      pos 5244
      pos 5248
      pos 5263
      pos 5270
      pos 5274
      pos 5284
      pos 5296
      pos 5300
      pos 5304
      pos 5308
      pos 5310
      pos 5323
      pos 5341
      pos 5356
      pos 5362
      pos 5370
      pos 5400
      pos 5410
      pos 5441
      pos 5445
      pos 5455
      pos 5458
      pos 5466
      pos 5480
      pos 5499
      pos 5502
      pos 5510
      pos 5560
      pos 5567
      pos 5575
      pos 5610
      pos 5614
      pos 5625
      pos 5639
      pos 5642
      pos 5645
      pos 5649
      pos 5663
      pos 5801
      pos 5811
      pos 5838
      pos 5862
      pos 5958
      pos 5967
      pos 5982
      pos 5991
      pos 6003
      pos 6005
      pos 6016
      pos 6020
      pos 6039
      pos 6042
      pos 6064
      pos 6070
      pos 6089
      pos 6094
      pos 6101
      pos 6134
      pos 6158
      pos 6171
      pos 6185
      pos 6202
      pos 6212
      pos 6247
      pos 6250
      pos 6259
      pos 6266
    doc 4
      freq 437
      pos 34
      pos 54
      pos 67
      pos 71
      pos 79
      pos 97
      pos 105
      pos 122
      pos 282
      pos 289
      pos 306
      pos 324
      pos 339
      pos 379
      pos 395
      pos 400
      pos 442
      pos 509
      pos 513
      pos 549
      pos 562
      pos 570
      pos 578
      pos 582
      pos 627
      pos 631
      pos 634
      pos 639
      pos 642
      pos 645
      pos 650
      pos 664
      pos 674
      pos 680
      pos 705
      pos 752
      pos 756
      pos 861
      pos 892
      pos 902
      pos 904
      pos 931
      pos 937
      pos 944
      pos 951
      pos 960
      pos 972
      pos 984
      pos 988
      pos 1022
      pos 1025
      pos 1032
      pos 1047
      pos 1055
      pos 1073
      pos 1080
      pos 1085
      pos 1088
      pos 1099
      pos 1103
      pos 1109
      pos 1121
      pos 1125
      pos 1129
      pos 1138
      pos 1162
      pos 1173
      pos 1175
      pos 1179
      pos 1189
      pos 1191
      pos 1198
      pos 1206
      pos 1215
      pos 1218
      pos 1222
      pos 1246
      pos 1249
      pos 1256
      pos 1259
      pos 1265
      pos 1270
      pos 1276
      pos 1297
      pos 1303
      pos 1308
      pos 1315
      pos 1326
      pos 1333
      pos 1335
      pos 1350
      pos 1394
      pos 1400
      pos 1404
      pos 1443
      pos 1448
      pos 1452
      pos 1458
      pos 1463
      pos 1472
      pos 1485
      pos 1489
      pos 1497
      pos 1502
      pos 1505
      pos 1513
      pos 1520
      pos 1531
      pos 1537
      pos 1540
      pos 1573
      pos 1582
      pos 1587
      pos 1612
      pos 1620
      pos 1623
      pos 1628
      pos 1644
      pos 1678
      pos 1697
      pos 1717
      pos 1737
      pos 1772
      pos 1797
      pos 1810
      pos 1826
      pos 1842
      pos 1866
      pos 1889
      pos 1898
      pos 1916
      pos 1936
      pos 1980
      pos 1988
      pos 1995
      pos 2001
      pos 2025
      pos 2036
      pos 2057
      pos 2061
      pos 2065
      pos 2140
      pos 2144
      pos 2155
      pos 2160
      pos 2219
      pos 2224
      pos 2239
      pos 2243
      pos 2280
      pos 2283
      pos 2294
      pos 2299
      pos 2340
      pos 2343
      pos 2354
      pos 2362
      pos 2365
      pos 2371
      pos 2375
      pos 2378
      pos 2381
      pos 2394
      pos 2397
      pos 2403
      pos 2406
      pos 2426
      pos 2432
      pos 2436
      pos 2439
      pos 2443
      pos 2446
      pos 2458
      pos 2474
      pos 2538
      pos 2547
      pos 2555
      pos 2577
      pos 2595
      pos 2598
      pos 2601
      pos 2607
      pos 2623
      pos 2631
      pos 2634
      pos 2640
      pos 2643
      pos 2649
      pos 2660
      pos 2668
      pos 2731
      pos 2738
      pos 2743
      pos 2806
      pos 2810
      pos 2821
      pos 2826
      pos 2839
      pos 2844
      pos 2847
      pos 2852
      pos 2877
      pos 2882
      pos 2885
      pos 2888
      pos 2898
      pos 2916
      pos 2984
      pos 2989
      pos 3051
      pos 3055
      pos 3066
      pos 3071
      pos 3106
      pos 3111
      pos 3140
      pos 3153
      pos 3156
      pos 3220
      pos 3225
      pos 3287
      pos 3291
      pos 3302
      pos 3307
      pos 3333
      pos 3337
      pos 3341
      pos 3345
      pos 3350
      pos 3353
      pos 3357
      pos 3367
      pos 3390
      pos 3402
      pos 3407
      pos 3418
      pos 3422
      pos 3427
      pos 3455
      pos 3458
      pos 3461
      pos 3466
      pos 3493
      pos 3498
      pos 3502
      pos 3523
      pos 3528
      pos 3766
      pos 3771
      pos 3783
      pos 3786
      pos 3808
      pos 3812
      pos 3818
      pos 3821
      pos 3865
      pos 3883
      pos 3886
      pos 3918
      pos 3922
      pos 3931
      pos 3935
      pos 3941
      pos 3945
      pos 3957
      pos 3972
      pos 3993
      pos 4004
      pos 4037
      pos 4053
      pos 4062
      pos 4073
      pos 4114
      pos 4141
      pos 4145
      pos 4155
      pos 4158
      pos 4168
      pos 4175
      pos 4189
      pos 4192
      pos 4205
      pos 4209
      pos 4219
      pos 4225
      pos 4232
      pos 4236
      pos 4241
      pos 4244
      pos 4248
      pos 4251
      pos 4262
      pos 4267
      pos 4270
      pos 4274
      pos 4280
      pos 4283
      pos 4289
      pos 4299
      pos 4303
      pos 4314
      pos 4318
      pos 4330
      pos 4335
      pos 4344
      pos 4387
      pos 4394
      pos 4409
      pos 4439
      pos 4462
      pos 4471
      pos 4478
      pos 4483
      pos 4489
      pos 4511
      pos 4522
      pos 4525
      pos 4536
      pos 4554
      pos 4567
      pos 4573
      pos 4584
      pos 4598
      pos 4610
      pos 4614
      pos 4617
      pos 4624
      pos 4631
      pos 4638
      pos 4644
      pos 4669
      pos 4672
      pos 4684
      pos 4698
      pos 4710
      pos 4714
      pos 4722
      pos 4731
      pos 4736
      pos 4754
      pos 4763
      pos 4791
      pos 4799
      pos 4803
      pos 4834
      pos 4841
      pos 4865
      pos 4867
      pos 4871
      pos 4892
      pos 4895
      pos 4908
      pos 4917
      pos 4922
      pos 4925
      pos 4930
      pos 4933
      pos 4940
      pos 4944
      pos 4949
      pos 4953
      pos 4972
      pos 4978
      pos 5003
      pos 5010
      pos 5023
      pos 5043
      pos 5046
      pos 5055
      pos 5067
      pos 5091
      pos 5095
      pos 5119
      pos 5123
      pos 5239
      pos 5316
      pos 5375
      pos 5431
      pos 5451
      pos 5460
      pos 5466
      pos 5517
      pos 5544
      pos 5553
      pos 5583
      pos 5587
      pos 5592
      pos 5628
      pos 5637
      pos 5642
      pos 5673
      pos 5709
      pos 5744
      pos 5781
      pos 5785
      pos 5804
      pos 5824
      pos 5829
      pos 5832
      pos 5840
      pos 5860
      pos 5886
      pos 5914
      pos 5940
      pos 5946
      pos 5955
      pos 5967
      pos 5978
      pos 5983
      pos 5987
      pos 5994
      pos 6017
      pos 6113
      pos 6122
      pos 6137
      pos 6146
      pos 6158
      pos 6160
      pos 6171
      pos 6175
      pos 6194
      pos 6197
      pos 6219
      pos 6225
      pos 6244
      pos 6249
      pos 6256
      pos 6289
      pos 6313
      pos 6326
      pos 6340
      pos 6357
      pos 6367
      pos 6402
      pos 6405
      pos 6414
      pos 6421
    doc 5
      freq 328
      pos 38
      pos 51
      pos 55
      pos 63
      pos 81
      pos 87
      pos 132
      pos 135
      pos 150
      pos 155
      pos 176
      pos 198
      pos 223
      pos 305
      pos 401
      pos 409
      pos 425
      pos 454
      pos 467
      pos 493
      pos 496
      pos 522
      pos 555
      pos 564
      pos 587
      pos 591
      pos 638
      pos 654
      pos 671
      pos 684
      pos 689
      pos 712
      pos 715
      pos 721
      pos 734
      pos 753
      pos 756
      pos 760
      pos 799
      pos 847
      pos 859
      pos 862
      pos 882
      pos 891
      pos 905
      pos 910
      pos 919
      pos 927
      pos 940
      pos 1011
      pos 1014
      pos 1022
      pos 1025
      pos 1046
      pos 1097
      pos 1117
      pos 1120
      pos 1125
      pos 1176
      pos 1192
      pos 1197
      pos 1211
      pos 1216
      pos 1226
      pos 1229
      pos 1232
      pos 1242
      pos 1245
      pos 1249
      pos 1252
      pos 1257
      pos 1270
      pos 1273
      pos 1277
      pos 1280
      pos 1283
      pos 1288
      pos 1300
      pos 1312
      pos 1315
      pos 1320
      pos 1323
      pos 1326
      pos 1336
      pos 1341
      pos 1365
      pos 1368
      pos 1371
      pos 1378
      pos 1381
      pos 1391
      pos 1405
      pos 1414
      pos 1418
      pos 1424
      pos 1438
      pos 1441
      pos 1449
      pos 1453
      pos 1456
      pos 1460
      pos 1464
      pos 1510
      pos 1521
      pos 1527
      pos 1535
      pos 1544
      pos 1560
      pos 1565
      pos 1625
      pos 1656
      pos 1661
      pos 1690
      pos 1706
      pos 1724
      pos 1728
      pos 1732
      pos 1755
      pos 1758
      pos 1762
      pos 1837
      pos 1840
      pos 1846
      pos 1849
      pos 1858
      pos 1861
      pos 1869
      pos 1873
      pos 1883
      pos 1886
      pos 1930
      pos 1978
      pos 1998
      pos 2059
      pos 2076
      pos 2090
      pos 2107
      pos 2116
      pos 2137
      pos 2141
      pos 2155
      pos 2165
      pos 2173
      pos 2177
      pos 2180
      pos 2186
      pos 2214
      pos 2220
      pos 2224
      pos 2235
      pos 2238
      pos 2263
      pos 2270
      pos 2280
      pos 2284
      pos 2290
      pos 2294
      pos 2305
      pos 2323
      pos 2327
      pos 2332
      pos 2337
      pos 2347
      pos 2364
      pos 2381
      pos 2416
      pos 2420
      pos 2435
      pos 2439
      pos 2442
      pos 2447
      pos 2459
      pos 2462
      pos 2488
      pos 2493
      pos 2506
      pos 2515
      pos 2520
      pos 2540
      pos 2568
      pos 2581
      pos 2604
      pos 2655
      pos 2664
      pos 2672
      pos 2713
      pos 2718
      pos 2724
      pos 2743
      pos 2792
      pos 2815
      pos 2822
      pos 2845
      pos 2862
      pos 2881
      pos 2900
      pos 2923
      pos 2928
      pos 2937
      pos 2957
      pos 2963
      pos 2975
      pos 2979
      pos 2991
      pos 3003
      pos 3006
      pos 3024
      pos 3030
      pos 3039
      pos 3078
      pos 3082
      pos 3092
      pos 3117
      pos 3129
      pos 3141
      pos 3145
      pos 3151
      pos 3164
      pos 3185
      pos 3205
      pos 3210
      pos 3218
      pos 3233
      pos 3265
      pos 3268
      pos 3296
      pos 3307
      pos 3319
      pos 3324
      pos 3331
      pos 3338
      pos 3343
      pos 3348
      pos 3365
      pos 3369
      pos 3379
      pos 3389
      pos 3423
      pos 3434
      pos 3442
      pos 3445
      pos 3451
      pos 3467
      pos 3472
      pos 3476
      pos 3499
      pos 3510
      pos 3519
      pos 3538
      pos 3550
      pos 3555
      pos 3577
      pos 3591
      pos 3614
      pos 3636
      pos 3666
      pos 3675
      pos 3686
      pos 3702
      pos 3705
      pos 3717
      pos 3721
      pos 3731
      pos 3734
      pos 3737
      pos 3750
      pos 3769
      pos 3774
      pos 3777
      pos 3785
      pos 3794
      pos 3802
      pos 3805
      pos 3816
      pos 3820
      pos 3847
      pos 3852
      pos 3859
      pos 3877
      pos 3882
      pos 3888
      pos 3894
      pos 3918
      pos 3933
      pos 3946
      pos 3969
      pos 3976
      pos 3981
      pos 3984
      pos 3988
      pos 3993
      pos 4001
      pos 4010
      pos 4018
      pos 4021
      pos 4035
      pos 4039
      pos 4043
      pos 4065
      pos 4077
      pos 4216
      pos 4227
      pos 4365
      pos 4443
      pos 4452
      pos 4467
      pos 4476
      pos 4488
      pos 4490
      pos 4501
      pos 4505
      pos 4524
      pos 4527
      pos 4549
      pos 4555
      pos 4574
      pos 4579
      pos 4586
      pos 4619
      pos 4643
      pos 4656
      pos 4670
      pos 4687
      pos 4697
      pos 4732
      pos 4735
      pos 4744
      pos 4751
    doc 6
      freq 206
      pos 34
      pos 57
      pos 84
      pos 110
      pos 115
      pos 142
      pos 253
      pos 270
      pos 305
      pos 310
      pos 327
      pos 362
      pos 372
      pos 385
      pos 390
      pos 404
      pos 440
      pos 461
      pos 481
      pos 509
      pos 513
      pos 519
      pos 544
      pos 572
      pos 586
      pos 599
      pos 615
      pos 621
      pos 625
      pos 631
      pos 636
      pos 642
      pos 652
      pos 655
      pos 678
      pos 694
      pos 704
      pos 715
      pos 781
      pos 787
      pos 795
      pos 843
      pos 847
      pos 851
      pos 874
      pos 904
      pos 914
      pos 925
      pos 972
      pos 1006
      pos 1009
      pos 1035
      pos 1037
      pos 1042
      pos 1053
      pos 1062
      pos 1066
      pos 1071
      pos 1081
      pos 1111
      pos 1120
      pos 1145
      pos 1151
      pos 1156
      pos 1164
      pos 1168
      pos 1173
      pos 1181
      pos 1187
      pos 1194
      pos 1198
      pos 1209
      pos 1222
      pos 1228
      pos 1244
      pos 1251
      pos 1255
      pos 1266
      pos 1269
      pos 1275
      pos 1278
      pos 1287
      pos 1302
      pos 1311
      pos 1314
      pos 1319
      pos 1352
      pos 1358
      pos 1394
      pos 1403
      pos 1410
      pos 1433
      pos 1465
      pos 1498
      pos 1517
      pos 1524
      pos 1535
      pos 1545
      pos 1567
      pos 1572
      pos 1579
      pos 1583
      pos 1587
      pos 1595
      pos 1598
      pos 1640
      pos 1650
      pos 1656
      pos 1672
      pos 1676
      pos 1684
      pos 1692
      pos 1754
      pos 1759
      pos 1764
      pos 1773
      pos 1778
      pos 1786
      pos 1792
      pos 1801
      pos 1807
      pos 1812
      pos 1822
      pos 1836
      pos 1841
      pos 1855
      pos 1859
      pos 1862
      pos 1866
      pos 1903
      pos 1910
      pos 1944
      pos 1958
      pos 1963
      pos 1976
      pos 1982
      pos 1985
      pos 1993
      pos 2018
      pos 2040
      pos 2045
      pos 2061
      pos 2157
      pos 2169
      pos 2176
      pos 2181
      pos 2195
      pos 2200
      pos 2231
      pos 2251
      pos 2266
      pos 2278
      pos 2360
      pos 2380
      pos 2392
      pos 2407
      pos 2429
      pos 2447
      pos 2449
      pos 2453
      pos 2477
      pos 2481
      pos 2522
      pos 2558
      pos 2611
      pos 2617
      pos 2674
      pos 2687
      pos 2690
      pos 2705
      pos 2712
      pos 2769
      pos 2779
      pos 2796
      pos 2800
      pos 2803
      pos 2816
      pos 2956
      pos 2977
      pos 3088
      pos 3092
      pos 3238
      pos 3247
      pos 3267
      pos 3276
      pos 3288
      pos 3290
      pos 3301
      pos 3305
      pos 3324
      pos 3327
      pos 3349
      pos 3355
      pos 3374
      pos 3379
      pos 3386
      pos 3419
      pos 3443
      pos 3456
      pos 3470
      pos 3487
      pos 3497
      pos 3532
      pos 3535
      pos 3544
      pos 3551
    doc 7
      freq 154
      pos 23
      pos 45
      pos 68
      pos 90
      pos 93
      pos 176
      pos 213
      pos 216
      pos 227
      pos 232
      pos 250
      pos 290
      pos 297
      pos 305
      pos 310
      pos 314
      pos 329
      pos 375
      pos 395
      pos 398
      pos 416
      pos 420
      pos 434
      pos 441
      pos 444
      pos 450
      pos 487
      pos 531
      pos 538
      pos 547
      pos 556
      pos 563
      pos 596
      pos 612
      pos 622
      pos 640
      pos 664
      pos 684
      pos 730
      pos 735
      pos 753
      pos 770
      pos 875
      pos 881
      pos 887
      pos 944
      pos 978
      pos 995
      pos 1079
      pos 1088
      pos 1106
      pos 1119
      pos 1137
      pos 1151
      pos 1156
      pos 1165
      pos 1236
      pos 1264
      pos 1286
      pos 1294
      pos 1329
      pos 1342
      pos 1354
      pos 1378
      pos 1432
      pos 1434
      pos 1463
      pos 1481
      pos 1496
      pos 1509
      pos 1518
      pos 1534
      pos 1538
      pos 1547
      pos 1555
      pos 1570
      pos 1573
      pos 1580
      pos 1584
      pos 1587
      pos 1594
      pos 1623
      pos 1628
      pos 1681
      pos 1691
      pos 1695
      pos 1702
      pos 1710
      pos 1713
      pos 1718
      pos 1776
      pos 1779
      pos 1798
      pos 1806
      pos 2012
      pos 2020
      pos 2067
      pos 2072
      pos 2091
      pos 2113
      pos 2123
      pos 2144
      pos 2160
      pos 2285
      pos 2291
      pos 2296
      pos 2303
      pos 2309
      pos 2313
      pos 2320
      pos 2326
      pos 2332
      pos 2339
      pos 2345
      pos 2351
      pos 2412
      pos 2430
      pos 2440
      pos 2483
      pos 2653
      pos 2656
      pos 2672
      pos 2681
      pos 2726
      pos 2754
      pos 2778
      pos 2817
      pos 2825
      pos 2834
      pos 2948
      pos 2957
      pos 2972
      pos 2981
      pos 2993
      pos 2995
      pos 3006
      pos 3010
      pos 3029
      pos 3032
      pos 3054
      pos 3060
      pos 3079
      pos 3084
      pos 3091
      pos 3124
      pos 3148
      pos 3161
      pos 3175
      pos 3192
      pos 3202
      pos 3237
      pos 3240
      pos 3249
      pos 3256
    doc 8
      freq 83
      pos 42
      pos 62
      pos 70
      pos 86
      pos 197
      pos 210
      pos 221
      pos 251
      pos 306
      pos 345
      pos 365
      pos 397
      pos 401
      pos 417
      pos 425
      pos 433
      pos 439
      pos 441
      pos 444
      pos 450
      pos 462
      pos 488
      pos 525
      pos 545
      pos 572
      pos 595
      pos 816
      pos 855
      pos 875
      pos 903
      pos 939
      pos 960
      pos 973
      pos 1097
      pos 1103
      pos 1106
      pos 1110
      pos 1145
      pos 1181
      pos 1201
      pos 1228
      pos 1267
      pos 1326
      pos 1362
      pos 1382
      pos 1409
      pos 1462
      pos 1516
      pos 1551
      pos 1632
      pos 1635
      pos 1650
      pos 1653
      pos 1687
      pos 1692
      pos 1696
      pos 1716
      pos 1803
      pos 2165
      pos 2174
      pos 2189
      pos 2198
      pos 2210
      pos 2212
      pos 2223
      pos 2227
      pos 2246
      pos 2249
      pos 2271
      pos 2277
      pos 2296
      pos 2301
      pos 2308
      pos 2341
      pos 2365
      pos 2378
      pos 2392
      pos 2409
      pos 2419
      pos 2454
      pos 2457
      pos 2466
      pos 2473
    doc 9
      freq 135
      pos 40
      pos 53
      pos 57
      pos 65
      pos 83
      pos 166
      pos 172
      pos 187
      pos 190
      pos 202
      pos 205
      pos 220
      pos 239
      pos 247
      pos 266
      pos 279
      pos 297
      pos 300
      pos 309
      pos 333
      pos 336
      pos 344
      pos 392
      pos 406
      pos 409
      pos 417
      pos 420
      pos 425
      pos 433
      pos 449
      pos 489
      pos 492
      pos 514
      pos 526
      pos 549
      pos 555
      pos 629
      pos 638
      pos 646
      pos 664
      pos 736
      pos 747
      pos 751
      pos 760
      pos 771
      pos 781
      pos 785
      pos 794
      pos 800
      pos 826
      pos 831
      pos 834
      pos 839
      pos 843
      pos 851
      pos 876
      pos 903
      pos 908
      pos 917
      pos 958
      pos 966
      pos 978
      pos 992
      pos 995
      pos 1028
      pos 1047
      pos 1062
      pos 1065
      pos 1101
      pos 1106
      pos 1114
      pos 1118
      pos 1131
      pos 1183
      pos 1207
      pos 1215
      pos 1229
      pos 1232
      pos 1245
      pos 1248
      pos 1255
      pos 1266
      pos 1276
      pos 1281
      pos 1292
      pos 1299
      pos 1314
      pos 1323
      pos 1346
      pos 1358
      pos 1418
      pos 1422
      pos 1428
      pos 1454
      pos 1467
      pos 1479
      pos 1486
      pos 1499
      pos 1513
      pos 1526
      pos 1546
      pos 1555
      pos 1576
      pos 1580
      pos 1585
      pos 1595
      pos 1598
      pos 1614
      pos 1629
      pos 1642
      pos 1810
      pos 1819
      pos 1834
      pos 1843
      pos 1855
      pos 1857
      pos 1868
      pos 1872
      pos 1891
      pos 1894
      pos 1916
      pos 1922
      pos 1941
      pos 1946
      pos 1953
      pos 1986
      pos 2010
      pos 2023
      pos 2037
      pos 2054
      pos 2064
      pos 2099
      pos 2102
      pos 2111
      pos 2118
    doc 10
      freq 954
      pos 25
      pos 43
      pos 56
      pos 60
      pos 68
      pos 86
      pos 91
      pos 96
      pos 106
      pos 109
      pos 151
      pos 161
      pos 164
      pos 258
      pos 286
      pos 289
      pos 409
      pos 417
      pos 428
      pos 474
      pos 481
      pos 493
      pos 502
      pos 552
      pos 572
      pos 575
      pos 609
      pos 634
      pos 645
      pos 664
      pos 674
      pos 713
      pos 742
      pos 752
      pos 770
      pos 779
      pos 807
      pos 825
      pos 829
      pos 835
      pos 844
      pos 855
      pos 932
      pos 945
      pos 948
      pos 954
      pos 984
      pos 1018
      pos 1028
      pos 1037
      pos 1045
      pos 1053
      pos 1108
      pos 1188
      pos 1201
      pos 1236
      pos 1239
      pos 1273
      pos 1282
      pos 1287
      pos 1299
      pos 1313
      pos 1323
      pos 1388
      pos 1391
      pos 1469
      pos 1482
      pos 1556
      pos 1567
      pos 1572
      pos 1665
      pos 1682
      pos 1743
      pos 1756
      pos 1769
      pos 1788
      pos 1795
      pos 1801
      pos 1807
      pos 1828
      pos 1833
      pos 1850
      pos 1870
      pos 1876
      pos 1894
      pos 1897
      pos 1914
      pos 1919
      pos 1922
      pos 1929
      pos 1932
      pos 1946
      pos 1949
      pos 1952
      pos 1955
      pos 1958
      pos 1967
      pos 1982
      pos 1984
      pos 1992
      pos 1996
      pos 2024
      pos 2028
      pos 2032
      pos 2040
      pos 2044
      pos 2048
      pos 2051
      pos 2056
      pos 2060
      pos 2111
      pos 2130
      pos 2136
      pos 2210
      pos 2266
      pos 2310
      pos 2316
      pos 2320
      pos 2325
      pos 2341
      pos 2346
      pos 2349
      pos 2352
      pos 2354
      pos 2361
      pos 2373
      pos 2377
      pos 2388
      pos 2393
      pos 2397
      pos 2404
      pos 2413
      pos 2427
      pos 2436
      pos 2440
      pos 2444
      pos 2447
      pos 2467
      pos 2474
      pos 2483
      pos 2522
      pos 2530
      pos 2533
      pos 2539
      pos 2543
      pos 2551
      pos 2556
      pos 2559
      pos 2573
      pos 2587
      pos 2595
      pos 2607
      pos 2639
      pos 2643
      pos 2652
      pos 2670
      pos 2691
      pos 2694
      pos 2698
      pos 2702
      pos 2706
      pos 2721
      pos 2728
      pos 2739
      pos 2747
      pos 2762
      pos 2766
      pos 2770
      pos 2778
      pos 2781
      pos 2786
      pos 2816
      pos 2831
      pos 2846
      pos 2849
      pos 2874
      pos 2879
      pos 2893
      pos 2902
      pos 2919
      pos 2922
      pos 2932
      pos 2937
      pos 2941
      pos 2957
      pos 2961
      pos 2984
      pos 2990
      pos 2997
      pos 3001
      pos 3004
      pos 3017
      pos 3021
      pos 3026
      pos 3029
      pos 3038
      pos 3043
      pos 3056
      pos 3076
      pos 3079
      pos 3087
      pos 3096
      pos 3101
      pos 3104
      pos 3112
      pos 3123
      pos 3142
      pos 3153
      pos 3164
      pos 3178
      pos 3187
      pos 3200
      pos 3205
      pos 3208
      pos 3213
      pos 3229
      pos 3241
      pos 3264
      pos 3270
      pos 3275
      pos 3285
      pos 3290
      pos 3300
      pos 3305
      pos 3314
      pos 3320
      pos 3327
      pos 3329
      pos 3339
      pos 3355
      pos 3380
      pos 3385
      pos 3400
      pos 3403
      pos 3412
      pos 3433
      pos 3446
      pos 3460
      pos 3480
      pos 3491
      pos 3525
      pos 3529
      pos 3534
      pos 3537
      pos 3549
      pos 3557
      pos 3561
      pos 3566
      pos 3580
      pos 3587
      pos 3590
      pos 3596
      pos 3599
      pos 3602
      pos 3624
      pos 3631
      pos 3634
      pos 3639
      pos 3649
      pos 3656
      pos 3669
      pos 3689
      pos 3705
      pos 3724
      pos 3734
      pos 3738
      pos 3744
      pos 3748
      pos 3767
      pos 3773
      pos 3821
      pos 3825
      pos 3828
      pos 3831
      pos 3834
      pos 3850
      pos 3901
      pos 3904
      pos 3917
      pos 3921
      pos 3927
      pos 3931
      pos 3934
      pos 3967
      pos 3975
      pos 3989
      pos 3993
      pos 4001
      pos 4014
      pos 4024
      pos 4044
      pos 4048
      pos 4065
      pos 4071
      pos 4082
      pos 4103
      pos 4112
      pos 4119
      pos 4142
      pos 4153
      pos 4157
      pos 4166
      pos 4171
      pos 4174
      pos 4192
      pos 4196
      pos 4199
      pos 4204
      pos 4208
      pos 4221
      pos 4224
      pos 4230
      pos 4246
      pos 4250
      pos 4258
      pos 4275
      pos 4284
      pos 4287
      pos 4292
      pos 4296
      pos 4306
      pos 4351
      pos 4354
      pos 4405
      pos 4408
      pos 4411
      pos 4424
      pos 4449
      pos 4472
      pos 4489
      pos 4494
      pos 4532
      pos 4549
      pos 4552
      pos 4577
      pos 4584
      pos 4608
      pos 4637
      pos 4666
      pos 4669
      pos 4689
      pos 4702
      pos 4705
      pos 4708
      pos 4733
      pos 4788
      pos 4796
      pos 4851
      pos 4873
      pos 4876
      pos 4880
      pos 4896
      pos 4909
      pos 4912
      pos 4915
      pos 4921
      pos 4930
      pos 4946
      pos 4951
      pos 4957
      pos 4961
      pos 4967
      pos 4975
      pos 4998
      pos 5011
      pos 5018
      pos 5032
      pos 5040
      pos 5044
      pos 5048
      pos 5052
      pos 5065
      pos 5083
      pos 5097
      pos 5102
      pos 5115
      pos 5120
      pos 5132
      pos 5141
      pos 5145
      pos 5154
      pos 5163
      pos 5168
      pos 5174
      pos 5194
      pos 5200
      pos 5204
      pos 5208
      pos 5211
      pos 5218
      pos 5221
      pos 5225
      pos 5238
      pos 5244
      pos 5247
      pos 5251
      pos 5263
      pos 5275
      pos 5289
      pos 5307
      pos 5317
      pos 5344
      pos 5352
      pos 5357
      pos 5365
      pos 5371
      pos 5379
      pos 5385
      pos 5391
      pos 5406
      pos 5418
      pos 5421
      pos 5423
      pos 5431
      pos 5435
      pos 5456
      pos 5487
      pos 5494
      pos 5500
      pos 5510
      pos 5527
      pos 5545
      pos 5550
      pos 5558
      pos 5566
      pos 5570
      pos 5584
      pos 5587
      pos 5597
      pos 5605
      pos 5616
      pos 5626
      pos 5632
      pos 5654
      pos 5658
      pos 5711
      pos 5724
      pos 5740
      pos 5773
      pos 5846
      pos 5855
      pos 5858
      pos 5885
      pos 5904
      pos 5928
      pos 5944
      pos 5950
      pos 5953
      pos 5957
      pos 5971
      pos 5974
      pos 5980
      pos 5991
      pos 5995
      pos 6004
      pos 6009
      pos 6015
      pos 6022
      pos 6028
      pos 6032
      pos 6037
      pos 6041
      pos 6062
      pos 6078
      pos 6110
      pos 6117
      pos 6130
      pos 6145
      pos 6161
      pos 6190
      pos 6303
      pos 6311
      pos 6317
      pos 6406
      pos 6410
      pos 6434
      pos 6440
      pos 6453
      pos 6455
      pos 6460
      pos 6467
      pos 6471
      pos 6542
      pos 6547
      pos 6557
      pos 6566
      pos 6600
      pos 6604
      pos 6708
      pos 6714
      pos 6722
      pos 6728
      pos 6731
      pos 6737
      pos 6742
      pos 6749
      pos 6753
      pos 6760
      pos 6764
      pos 6768
      pos 6773
      pos 6793
      pos 6799
      pos 6818
      pos 6929
      pos 6932
      pos 6936
      pos 6942
      pos 6950
      pos 6956
      pos 7010
      pos 7014
      pos 7038
      pos 7044
      pos 7059
      pos 7073
      pos 7081
      pos 7085
      pos 7089
      pos 7096
      pos 7104
      pos 7172
      pos 7176
      pos 7180
      pos 7193
      pos 7205
      pos 7210
      pos 7217
      pos 7221
      pos 7245
      pos 7250
      pos 7262
      pos 7284
      pos 7316
      pos 7320
      pos 7387
      pos 7393
      pos 7419
      pos 7428
      pos 7440
      pos 7457
      pos 7460
      pos 7477
      pos 7491
      pos 7499
      pos 7523
      pos 7527
      pos 7533
      pos 7540
      pos 7551
      pos 7556
      pos 7569
      pos 7580
      pos 7588
      pos 7639
      pos 7651
      pos 7679
      pos 7703
      pos 7719
      pos 7748
      pos 7769
      pos 7779
      pos 7818
      pos 7847
      pos 7850
      pos 7854
      pos 7880
      pos 7884
      pos 7888
      pos 7916
      pos 7920
      pos 7950
      pos 7953
      pos 7962
      pos 7975
      pos 7990
      pos 8000
      pos 8007
      pos 8042
      pos 8051
      pos 8056
      pos 8062
      pos 8071
      pos 8083
      pos 8095
      pos 8107
      pos 8121
      pos 8132
      pos 8142
      pos 8146
      pos 8151
      pos 8160
      pos 8169
      pos 8189
      pos 8224
      pos 8242
      pos 8254
      pos 8268
      pos 8282
      pos 8286
      pos 8292
      pos 8314
      pos 8318
      pos 8331
      pos 8340
      pos 8346
      pos 8351
      pos 8354
      pos 8357
      pos 8360
      pos 8367
      pos 8372
      pos 8379
      pos 8384
      pos 8389
      pos 8392
      pos 8400
      pos 8405
      pos 8443
      pos 8448
      pos 8456
      pos 8472
      pos 8506
      pos 8511
      pos 8522
      pos 8550
      pos 8568
      pos 8576
      pos 8585
      pos 8592
      pos 8605
      pos 8628
      pos 8639
      pos 8643
      pos 8652
      pos 8655
      pos 8658
      pos 8661
      pos 8689
      pos 8708
      pos 8716
      pos 8727
      pos 8745
      pos 8754
      pos 8766
      pos 8769
      pos 8780
      pos 8790
      pos 8794
      pos 8799
      pos 8830
      pos 8834
      pos 8846
      pos 8851
      pos 8878
      pos 8887
      pos 8894
      pos 8906
      pos 8910
      pos 8933
      pos 8940
      pos 8946
      pos 8969
      pos 8974
      pos 9001
      pos 9012
      pos 9047
      pos 9056
      pos 9064
      pos 9075
      pos 9080
      pos 9105
      pos 9108
      pos 9126
      pos 9140
      pos 9152
      pos 9169
      pos 9177
      pos 9198
      pos 9213
      pos 9218
      pos 9244
      pos 9248
      pos 9251
      pos 9272
      pos 9288
      pos 9329
      pos 9411
      pos 9419
      pos 9422
      pos 9429
      pos 9437
      pos 9443
      pos 9456
      pos 9460
      pos 9468
      pos 9500
      pos 9525
      pos 9544
      pos 9554
      pos 9572
      pos 9577
      pos 9585
      pos 9588
      pos 9608
      pos 9614
      pos 9632
      pos 9640
      pos 9654
      pos 9680
      pos 9705
      pos 9728
      pos 9732
      pos 9740
      pos 9758
      pos 9763
      pos 9769
      pos 9780
      pos 9785
      pos 9819
      pos 9844
      pos 9851
      pos 9857
      pos 9867
      pos 9881
      pos 9886
      pos 9903
      pos 9921
      pos 9949
      pos 9974
      pos 9991
      pos 10010
      pos 10013
      pos 10016
      pos 10043
      pos 10058
      pos 10068
      pos 10073
      pos 10121
      pos 10127
      pos 10130
      pos 10138
      pos 10154
      pos 10161
      pos 10167
      pos 10184
      pos 10189
      pos 10211
      pos 10214
      pos 10239
      pos 10242
      pos 10247
      pos 10278
      pos 10301
      pos 10315
      pos 10340
      pos 10352
      pos 10357
      pos 10382
      pos 10386
      pos 10389
      pos 10394
      pos 10397
      pos 10402
      pos 10405
      pos 10409
      pos 10432
      pos 10477
      pos 10500
      pos 10528
      pos 10552
      pos 10569
      pos 10573
      pos 10576
      pos 10586
      pos 10598
      pos 10617
      pos 10620
      pos 10628
      pos 10634
      pos 10638
      pos 10642
      pos 10657
      pos 10660
      pos 10665
      pos 10669
      pos 10692
      pos 10697
      pos 10707
      pos 10710
      pos 10743
      pos 10746
      pos 10750
      pos 10755
      pos 10769
      pos 10775
      pos 10798
      pos 10801
      pos 10806
      pos 10810
      pos 10814
      pos 10827
      pos 10841
      pos 10844
      pos 10870
      pos 10885
      pos 10900
      pos 10954
      pos 10992
      pos 11009
      pos 11022
      pos 11026
      pos 11030
      pos 11045
      pos 11080
      pos 11167
      pos 11183
      pos 11218
      pos 11224
      pos 11253
      pos 11270
      pos 11304
      pos 11321
      pos 11330
      pos 11345
      pos 11350
      pos 11370
      pos 11375
      pos 11380
      pos 11396
      pos 11399
      pos 11417
      pos 11450
      pos 11458
      pos 11465
      pos 11474
      pos 11505
      pos 11513
      pos 11589
      pos 11605
      pos 11613
      pos 11661
      pos 11673
      pos 11676
      pos 11682
      pos 11685
      pos 11689
      pos 11700
      pos 11708
      pos 11755
      pos 11759
      pos 11763
      pos 11766
      pos 11773
      pos 11787
      pos 11801
      pos 11809
      pos 11868
      pos 11882
      pos 11887
      pos 11895
      pos 11903
      pos 11930
      pos 11958
      pos 11963
      pos 11968
      pos 11975
      pos 11978
      pos 11981
      pos 11985
      pos 11992
      pos 12010
      pos 12041
      pos 12046
      pos 12051
      pos 12058
      pos 12061
      pos 12066
      pos 12070
      pos 12077
      pos 12103
      pos 12148
      pos 12150
      pos 12158
      pos 12185
      pos 12200
      pos 12204
      pos 12220
      pos 12226
      pos 12236
      pos 12240
      pos 12247
      pos 12253
      pos 12260
      pos 12264
      pos 12270
      pos 12278
      pos 12283
      pos 12287
      pos 12297
      pos 12314
      pos 12317
      pos 12322
      pos 12326
      pos 12331
      pos 12335
      pos 12339
      pos 12346
      pos 12351
      pos 12362
      pos 12366
      pos 12420
      pos 12841
      pos 12847
      pos 12850
      pos 12864
      pos 12980
      pos 12986
      pos 13000
      pos 13007
      pos 13023
      pos 13053
      pos 13069
      pos 13073
      pos 13142
      pos 13215
      pos 13297
      pos 13315
      pos 13343
      pos 13471
      pos 13480
      pos 13495
      pos 13504
      pos 13516
      pos 13518
      pos 13529
      pos 13533
      pos 13552
      pos 13555
      pos 13577
      pos 13583
      pos 13602
      pos 13607
      pos 13614
      pos 13647
      pos 13671
      pos 13684
      pos 13698
      pos 13715
      pos 13725
      pos 13760
      pos 13763
      pos 13772
      pos 13779
    doc 11
      freq 310
      pos 47
      pos 70
      pos 153
      pos 580
      pos 585
      pos 599
      pos 615
      pos 620
      pos 638
      pos 641
      pos 729
      pos 734
      pos 798
      pos 802
      pos 811
      pos 838
      pos 854
      pos 863
      pos 866
      pos 895
      pos 908
      pos 923
      pos 937
      pos 942
      pos 945
      pos 1053
      pos 1056
      pos 1072
      pos 1080
      pos 1127
      pos 1269
      pos 1359
      pos 1386
      pos 1397
      pos 1403
      pos 1406
      pos 1429
      pos 1606
      pos 1609
      pos 1639
      pos 1647
      pos 1667
      pos 1684
      pos 1691
      pos 1710
      pos 1725
      pos 1742
      pos 1749
      pos 1755
      pos 1762
      pos 1787
      pos 1809
      pos 1811
      pos 1861
      pos 1881
      pos 2006
      pos 2012
      pos 2020
      pos 2028
      pos 2031
      pos 2049
      pos 2055
      pos 2067
      pos 2074
      pos 2079
      pos 2128
      pos 2131
      pos 2135
      pos 2142
      pos 2146
      pos 2165
      pos 2173
      pos 2181
      pos 2312
      pos 2314
      pos 2331
      pos 2345
      pos 2416
      pos 2433
      pos 2436
      pos 2445
      pos 2457
      pos 2462
      pos 2476
      pos 2516
      pos 2521
      pos 2622
      pos 2633
      pos 2636
      pos 2641
      pos 2732
      pos 2735
      pos 2752
      pos 2770
      pos 3227
      pos 3233
      pos 3242
      pos 3276
      pos 3282
      pos 3292
      pos 3300
      pos 3302
      pos 3309
      pos 3466
      pos 3470
      pos 3489
      pos 3496
      pos 3576
      pos 3598
      pos 3705
      pos 3722
      pos 3736
      pos 3739
      pos 3760
      pos 3929
      pos 4096
      pos 4100
      pos 4225
      pos 4241
      pos 4362
      pos 4366
      pos 4377
      pos 4417
      pos 4428
      pos 4432
      pos 4553
      pos 4556
      pos 4570
      pos 4577
      pos 4582
      pos 4596
      pos 4603
      pos 4614
      pos 4634
      pos 4758
      pos 4767
      pos 4774
      pos 4782
      pos 4805
      pos 4810
      pos 4817
      pos 4823
      pos 4827
      pos 4833
      pos 4839
      pos 4848
      pos 4872
      pos 4876
      pos 4880
      pos 4966
      pos 4975
      pos 4996
      pos 5092
      pos 5096
      pos 5122
      pos 5253
      pos 5290
      pos 5293
      pos 5296
      pos 5302
      pos 5305
      pos 5413
      pos 5434
      pos 5565
      pos 5594
      pos 5597
      pos 5600
      pos 5611
      pos 5723
      pos 5728
      pos 5731
      pos 5760
      pos 5763
      pos 5766
      pos 5777
      pos 5852
      pos 5887
      pos 5891
      pos 5896
      pos 5903
      pos 5907
      pos 5918
      pos 5922
      pos 5969
      pos 6049
      pos 6070
      pos 6073
      pos 6104
      pos 6126
      pos 6265
      pos 6270
      pos 6279
      pos 6290
      pos 6324
      pos 6392
      pos 6396
      pos 6429
      pos 6501
      pos 6505
      pos 6547
      pos 6560
      pos 6563
      pos 6571
      pos 6587
      pos 6656
      pos 6661
      pos 6737
      pos 6740
      pos 6744
      pos 6809
      pos 6969
      pos 7034
      pos 7038
      pos 7062
      pos 7074
      pos 7091
      pos 7191
      pos 7290
      pos 7326
      pos 7329
      pos 7347
      pos 7350
      pos 7355
      pos 7366
      pos 7481
      pos 7567
      pos 7577
      pos 7617
      pos 7713
      pos 7722
      pos 7726
      pos 7908
      pos 7936
      pos 7947
      pos 7963
      pos 7972
      pos 8012
      pos 8082
      pos 8283
      pos 8286
      pos 8300
      pos 8307
      pos 8395
      pos 8433
      pos 8559
      pos 8573
      pos 8586
      pos 8590
      pos 8662
      pos 8681
      pos 8711
      pos 8776
      pos 8782
      pos 8791
      pos 8802
      pos 8881
      pos 8887
      pos 8896
      pos 8900
      pos 8905
      pos 8974
      pos 8987
      pos 8996
      pos 9004
      pos 9028
      pos 9032
      pos 9186
      pos 9218
      pos 9227
      pos 9230
      pos 9321
      pos 9359
      pos 9423
      pos 9507
      pos 9545
      pos 9552
      pos 9556
      pos 9576
      pos 9737
      pos 9754
      pos 9763
      pos 9768
      pos 9779
      pos 9783
      pos 9827
      pos 10632
      pos 10641
      pos 10656
      pos 10665
      pos 10677
      pos 10679
      pos 10690
      pos 10694
      pos 10713
      pos 10716
      pos 10738
      pos 10744
      pos 10763
      pos 10768
      pos 10775
      pos 10808
      pos 10832
      pos 10845
      pos 10859
      pos 10876
      pos 10886
      pos 10921
      pos 10924
      pos 10933
      pos 10940
    doc 12
      freq 576
      pos 37
      pos 60
      pos 115
      pos 266
      pos 277
      pos 286
      pos 489
      pos 546
      pos 580
      pos 596
      pos 630
      pos 634
      pos 645
      pos 659
      pos 666
      pos 678
      pos 693
      pos 695
      pos 709
      pos 736
      pos 755
      pos 766
      pos 777
      pos 781
      pos 806
      pos 812
      pos 818
      pos 832
      pos 840
      pos 904
      pos 910
      pos 918
      pos 934
      pos 954
      pos 967
      pos 995
      pos 1002
      pos 1020
      pos 1023
      pos 1034
      pos 1049
      pos 1061
      pos 1065
      pos 1090
      pos 1111
      pos 1176
      pos 1179
      pos 1186
      pos 1198
      pos 1256
      pos 1277
      pos 1316
      pos 1341
      pos 1354
      pos 1364
      pos 1367
      pos 1386
      pos 1421
      pos 1474
      pos 1539
      pos 1587
      pos 1593
      pos 1600
      pos 1649
      pos 1726
      pos 1731
      pos 1744
      pos 1766
      pos 1770
      pos 1778
      pos 1789
      pos 1825
      pos 1835
      pos 1861
      pos 1866
      pos 1873
      pos 1963
      pos 2007
      pos 2075
      pos 2137
      pos 2162
      pos 2171
      pos 2177
      pos 2207
      pos 2213
      pos 2245
      pos 2264
      pos 2288
      pos 2296
      pos 2314
      pos 2355
      pos 2358
      pos 2365
      pos 2373
      pos 2392
      pos 2401
      pos 2426
      pos 2437
      pos 2442
      pos 2490
      pos 2493
      pos 2500
      pos 2507
      pos 2514
      pos 2521
      pos 2535
      pos 2544
      pos 2549
      pos 2552
      pos 2555
      pos 2560
      pos 2563
      pos 2573
      pos 2579
      pos 2585
      pos 2593
      pos 2596
      pos 2605
      pos 2640
      pos 2657
      pos 2670
      pos 2679
      pos 2683
      pos 2692
      pos 2709
      pos 2722
      pos 2734
      pos 2738
      pos 2764
      pos 2792
      pos 2801
      pos 2816
      pos 2866
      pos 2875
      pos 2906
      pos 2925
      pos 2931
      pos 2934
      pos 2949
      pos 2955
      pos 2970
      pos 2975
      pos 2979
      pos 2986
      pos 2993
      pos 3010
      pos 3033
      pos 3036
      pos 3045
      pos 3055
      pos 3059
      pos 3072
      pos 3080
      pos 3086
      pos 3097
      pos 3103
      pos 3107
      pos 3113
      pos 3125
      pos 3130
      pos 3134
      pos 3154
      pos 3190
      pos 3211
      pos 3240
      pos 3255
      pos 3260
      pos 3273
      pos 3286
      pos 3298
      pos 3301
      pos 3317
      pos 3330
      pos 3348
      pos 3363
      pos 3369
      pos 3393
      pos 3406
      pos 3410
      pos 3455
      pos 3458
      pos 3476
      pos 3488
      pos 3492
      pos 3505
      pos 3528
      pos 3536
      pos 3540
      pos 3551
      pos 3557
      pos 3571
      pos 3590
      pos 3606
      pos 3619
      pos 3652
      pos 3658
      pos 3662
      pos 3665
      pos 3683
      pos 3688
      pos 3693
      pos 3700
      pos 3705
      pos 3731
      pos 3740
      pos 3745
      pos 3754
      pos 3760
      pos 3787
      pos 3821
      pos 3831
      pos 3854
      pos 3901
      pos 3949
      pos 3984
      pos 4006
      pos 4010
      pos 4017
      pos 4060
      pos 4066
      pos 4073
      pos 4130
      pos 4148
      pos 4210
      pos 4217
      pos 4221
      pos 4226
      pos 4242
      pos 4260
      pos 4264
      pos 4286
      pos 4290
      pos 4346
      pos 4377
      pos 4423
      pos 4462
      pos 4484
      pos 4494
      pos 4498
      pos 4543
      pos 4577
      pos 4581
      pos 4584
      pos 4586
      pos 4592
      pos 4601
      pos 4606
      pos 4619
      pos 4622
      pos 4636
      pos 4641
      pos 4653
      pos 4687
      pos 4694
      pos 4697
      pos 4714
      pos 4717
      pos 4726
      pos 4734
      pos 4739
      pos 4741
      pos 4752
      pos 4763
      pos 4771
      pos 4783
      pos 4797
      pos 4802
      pos 4810
      pos 4819
      pos 4824
      pos 4831
      pos 4834
      pos 4846
      pos 4851
      pos 4865
      pos 4872
      pos 4877
      pos 4884
      pos 4902
      pos 4925
      pos 4934
      pos 4946
      pos 4952
      pos 4973
      pos 5000
      pos 5020
      pos 5023
      pos 5026
      pos 5052
      pos 5062
      pos 5065
      pos 5068
      pos 5072
      pos 5081
      pos 5084
      pos 5089
      pos 5117
      pos 5121
      pos 5130
      pos 5141
      pos 5166
      pos 5213
      pos 5218
      pos 5228
      pos 5248
      pos 5320
      pos 5325
      pos 5328
      pos 5363
      pos 5394
      pos 5399
      pos 5457
      pos 5465
      pos 5482
      pos 5488
      pos 5501
      pos 5507
      pos 5512
      pos 5529
      pos 5552
      pos 5555
      pos 5558
      pos 5565
      pos 5583
      pos 5586
      pos 5609
      pos 5619
      pos 5623
      pos 5638
      pos 5663
      pos 5675
      pos 5696
      pos 5708
      pos 5725
      pos 5734
      pos 5739
      pos 5747
      pos 5755
      pos 5786
      pos 5788
      pos 5792
      pos 5797
      pos 5816
      pos 5825
      pos 5831
      pos 5835
      pos 5885
      pos 5900
      pos 5908
      pos 5925
      pos 5940
      pos 5943
      pos 5947
      pos 5955
      pos 5964
      pos 5968
      pos 6013
      pos 6073
      pos 6076
      pos 6081
      pos 6085
      pos 6114
      pos 6147
      pos 6182
      pos 6185
      pos 6195
      pos 6202
      pos 6206
      pos 6211
      pos 6214
      pos 6222
      pos 6225
      pos 6231
      pos 6238
      pos 6261
      pos 6265
      pos 6284
      pos 6287
      pos 6290
      pos 6298
      pos 6302
      pos 6309
      pos 6313
      pos 6318
      pos 6333
      pos 6353
      pos 6364
      pos 6370
      pos 6377
      pos 6385
      pos 6389
      pos 6395
      pos 6403
      pos 6407
      pos 6413
      pos 6443
      pos 6446
      pos 6451
      pos 6475
      pos 6524
      pos 6541
      pos 6564
      pos 6577
      pos 6605
      pos 6619
      pos 6622
      pos 6662
      pos 6679
      pos 6688
      pos 6697
      pos 6705
      pos 6710
      pos 6714
      pos 6734
      pos 6740
      pos 6790
      pos 6796
      pos 6820
      pos 6830
      pos 6839
      pos 6870
      pos 6887
      pos 6897
      pos 6922
      pos 6947
      pos 6959
      pos 7024
      pos 7042
      pos 7216
      pos 7501
      pos 7519
      pos 7691
      pos 7814
      pos 7847
      pos 7906
      pos 7914
      pos 7917
      pos 7919
      pos 7933
      pos 7955
      pos 7968
      pos 7972
      pos 7975
      pos 7980
      pos 7989
      pos 8000
      pos 8012
      pos 8021
      pos 8029
      pos 8034
      pos 8043
      pos 8053
      pos 8096
      pos 8109
      pos 8139
      pos 8170
      pos 8175
      pos 8183
      pos 8220
      pos 8288
      pos 8294
      pos 8310
      pos 8316
      pos 8320
      pos 8324
      pos 8328
      pos 8348
      pos 8351
      pos 8357
      pos 8369
      pos 8390
      pos 8400
      pos 8410
      pos 8437
      pos 8447
      pos 8477
      pos 8481
      pos 8495
      pos 8498
      pos 8507
      pos 8512
      pos 8528
      pos 8552
      pos 8564
      pos 8568
      pos 8577
      pos 8580
      pos 8590
      pos 8602
      pos 8612
      pos 8624
      pos 8660
      pos 8694
      pos 8709
      pos 8718
      pos 8721
      pos 8733
      pos 8737
      pos 8745
      pos 8749
      pos 8758
      pos 8802
      pos 8806
      pos 8821
      pos 8835
      pos 8857
      pos 8876
      pos 8879
      pos 8884
      pos 8894
      pos 8898
      pos 8904
      pos 8912
      pos 8928
      pos 8931
      pos 8950
      pos 8995
      pos 9012
      pos 9017
      pos 9027
      pos 9037
      pos 9058
      pos 9064
      pos 9071
      pos 9096
      pos 9102
      pos 9117
      pos 9123
      pos 9131
      pos 9138
      pos 9147
      pos 9151
      pos 9159
      pos 9162
      pos 9167
      pos 9172
      pos 9184
      pos 9191
      pos 9198
      pos 9202
      pos 9212
      pos 9259
      pos 9276
      pos 9281
      pos 9294
      pos 9314
      pos 9331
      pos 9340
      pos 9367
      pos 9375
      pos 9410
      pos 9482
      pos 9491
      pos 9506
      pos 9515
      pos 9527
      pos 9529
      pos 9540
      pos 9544
      pos 9563
      pos 9566
      pos 9588
      pos 9594
      pos 9613
      pos 9618
      pos 9625
      pos 9658
      pos 9682
      pos 9695
      pos 9709
      pos 9726
      pos 9736
      pos 9771
      pos 9774
      pos 9783
      pos 9790
    doc 13
      freq 294
      pos 46
      pos 69
      pos 396
      pos 401
      pos 413
      pos 424
      pos 445
      pos 486
      pos 507
      pos 530
      pos 554
      pos 562
      pos 644
      pos 655
      pos 669
      pos 688
      pos 718
      pos 810
      pos 817
      pos 833
      pos 844
      pos 871
      pos 881
      pos 934
      pos 992
      pos 996
      pos 1001
      pos 1074
      pos 1169
      pos 1172
      pos 1182
      pos 1227
      pos 1235
      pos 1238
      pos 1246
      pos 1283
      pos 1306
      pos 1322
      pos 1421
      pos 1428
      pos 1485
      pos 1513
      pos 1517
      pos 1527
      pos 1542
      pos 1545
      pos 1548
      pos 1562
      pos 1583
      pos 1588
      pos 1594
      pos 1660
      pos 1735
      pos 1744
      pos 1752
      pos 1792
      pos 1843
      pos 1947
      pos 1958
      pos 1991
      pos 2021
      pos 2117
      pos 2187
      pos 2193
      pos 2212
      pos 2220
      pos 2231
      pos 2266
      pos 2293
      pos 2312
      pos 2372
      pos 2423
      pos 2482
      pos 2507
      pos 2531
      pos 2546
      pos 2681
      pos 2751
      pos 2757
      pos 2771
      pos 2834
      pos 2849
      pos 2883
      pos 2888
      pos 2974
      pos 2981
      pos 2985
      pos 2988
      pos 2990
      pos 3013
      pos 3024
      pos 3059
      pos 3090
      pos 3097
      pos 3119
      pos 3124
      pos 3148
      pos 3161
      pos 3171
      pos 3181
      pos 3209
      pos 3213
      pos 3267
      pos 3286
      pos 3315
      pos 3323
      pos 3335
      pos 3348
      pos 3408
      pos 3417
      pos 3431
      pos 3500
      pos 3526
      pos 3542
      pos 3553
      pos 3568
      pos 3573
      pos 3582
      pos 3597
      pos 3603
      pos 3648
      pos 3686
      pos 3736
      pos 3742
      pos 3764
      pos 3810
      pos 3823
      pos 3829
      pos 3838
      pos 3852
      pos 3877
      pos 3880
      pos 3899
      pos 3938
      pos 3950
      pos 3977
      pos 4049
      pos 4070
      pos 4157
      pos 4164
      pos 4169
      pos 4191
      pos 4212
      pos 4223
      pos 4243
      pos 4250
      pos 4254
      pos 4259
      pos 4276
      pos 4316
      pos 4348
      pos 4357
      pos 4369
      pos 4378
      pos 4387
      pos 4396
      pos 4415
      pos 4423
      pos 4447
      pos 4463
      pos 4471
      pos 4478
      pos 4489
      pos 4493
      pos 4516
      pos 4525
      pos 4534
      pos 4543
      pos 4553
      pos 4556
      pos 4567
      pos 4593
      pos 4603
      pos 4660
      pos 4696
      pos 4723
      pos 4729
      pos 4735
      pos 4738
      pos 4747
      pos 4755
      pos 4765
      pos 4777
      pos 4782
      pos 4785
      pos 4803
      pos 4807
      pos 4815
      pos 4824
      pos 4838
      pos 4879
      pos 4883
      pos 4889
      pos 4895
      pos 4898
      pos 4901
      pos 4909
      pos 4912
      pos 4938
      pos 4944
      pos 4981
      pos 4997
      pos 5056
      pos 5078
      pos 5092
      pos 5148
      pos 5167
      pos 5171
      pos 5178
      pos 5194
      pos 5204
      pos 5208
      pos 5217
      pos 5277
      pos 5294
      pos 5318
      pos 5333
      pos 5337
      pos 5340
      pos 5348
      pos 5353
      pos 5358
      pos 5367
      pos 5429
      pos 5450
      pos 5461
      pos 5474
      pos 5505
      pos 5519
      pos 5531
      pos 5535
      pos 5571
      pos 5598
      pos 5614
      pos 5634
      pos 5640
      pos 5687
      pos 5720
      pos 5739
      pos 5748
      pos 5773
      pos 5779
      pos 5804
      pos 5821
      pos 5838
      pos 5853
      pos 5864
      pos 5878
      pos 5893
      pos 5919
      pos 5930
      pos 5972
      pos 5987
      pos 5997
      pos 6036
      pos 6051
      pos 6132
      pos 6192
      pos 6248
      pos 6292
      pos 6375
      pos 6383
      pos 6398
      pos 6613
      pos 6643
      pos 6662
      pos 6698
      pos 6869
      pos 6954
      pos 7097
      pos 7106
      pos 7121
      pos 7130
      pos 7142
      pos 7144
      pos 7155
      pos 7159
      pos 7178
      pos 7181
      pos 7203
      pos 7209
      pos 7228
      pos 7233
      pos 7240
      pos 7273
      pos 7297
      pos 7310
      pos 7324
      pos 7341
      pos 7351
      pos 7386
      pos 7389
      pos 7398
      pos 7405
    doc 14
      freq 278
      pos 34
      pos 64
      pos 76
      pos 286
      pos 290
      pos 296
      pos 317
      pos 325
      pos 338
      pos 397
      pos 438
      pos 460
      pos 504
      pos 508
      pos 511
      pos 528
      pos 536
      pos 542
      pos 570
      pos 646
      pos 655
      pos 700
      pos 703
      pos 707
      pos 716
      pos 724
      pos 733
      pos 740
      pos 745
      pos 759
      pos 771
      pos 776
      pos 783
      pos 792
      pos 797
      pos 808
      pos 811
      pos 818
      pos 851
      pos 864
      pos 870
      pos 890
      pos 897
      pos 921
      pos 936
      pos 945
      pos 956
      pos 962
      pos 975
      pos 983
      pos 988
      pos 995
      pos 1000
      pos 1003
      pos 1010
      pos 1020
      pos 1042
      pos 1051
      pos 1054
      pos 1061
      pos 1066
      pos 1076
      pos 1079
      pos 1083
      pos 1093
      pos 1107
      pos 1154
      pos 1174
      pos 1180
      pos 1186
      pos 1193
      pos 1201
      pos 1204
      pos 1208
      pos 1244
      pos 1276
      pos 1285
      pos 1316
      pos 1325
      pos 1331
      pos 1343
      pos 1371
      pos 1375
      pos 1400
      pos 1404
      pos 1408
      pos 1422
      pos 1426
      pos 1431
      pos 1436
      pos 1450
      pos 1462
      pos 1473
      pos 1477
      pos 1481
      pos 1488
      pos 1497
      pos 1502
      pos 1508
      pos 1511
      pos 1530
      pos 1539
      pos 1577
      pos 1581
      pos 1585
      pos 1599
      pos 1603
      pos 1607
      pos 1612
      pos 1627
      pos 1635
      pos 1640
      pos 1647
      pos 1652
      pos 1655
      pos 1662
      pos 1672
      pos 1694
      pos 1703
      pos 1706
      pos 1713
      pos 1718
      pos 1729
      pos 1734
      pos 1744
      pos 1753
      pos 1757
      pos 1768
      pos 1777
      pos 1796
      pos 1813
      pos 1819
      pos 1825
      pos 1831
      pos 1902
      pos 1948
      pos 1954
      pos 1961
      pos 1983
      pos 2010
      pos 2021
      pos 2028
      pos 2038
      pos 2045
      pos 2080
      pos 2096
      pos 2110
      pos 2115
      pos 2130
      pos 2170
      pos 2229
      pos 2232
      pos 2251
      pos 2269
      pos 2320
      pos 2326
      pos 2358
      pos 2368
      pos 2382
      pos 2389
      pos 2392
      pos 2403
      pos 2413
      pos 2416
      pos 2421
      pos 2426
      pos 2437
      pos 2440
      pos 2456
      pos 2462
      pos 2466
      pos 2470
      pos 2473
      pos 2490
      pos 2498
      pos 2512
      pos 2538
      pos 2579
      pos 2582
      pos 2591
      pos 2595
      pos 2602
      pos 2628
      pos 2647
      pos 2663
      pos 2686
      pos 2691
      pos 2694
      pos 2699
      pos 2703
      pos 2707
      pos 2721
      pos 2731
      pos 2734
      pos 2765
      pos 2779
      pos 2797
      pos 2820
      pos 2830
      pos 2838
      pos 2848
      pos 2864
      pos 2870
      pos 2881
      pos 2887
      pos 2890
      pos 2894
      pos 2913
      pos 3221
      pos 3244
      pos 3280
      pos 3827
      pos 3853
      pos 3857
      pos 3864
      pos 3868
      pos 3874
      pos 4169
      pos 4235
      pos 4300
      pos 4306
      pos 4313
      pos 4422
      pos 4428
      pos 4436
      pos 4443
      pos 4516
      pos 4598
      pos 4604
      pos 4610
      pos 4614
      pos 4982
      pos 5001
      pos 5018
      pos 5031
      pos 5035
      pos 5042
      pos 5046
      pos 5052
      pos 5155
      pos 5170
      pos 5178
      pos 5182
      pos 5277
      pos 5284
      pos 5292
      pos 5313
      pos 5317
      pos 5323
      pos 5337
      pos 5398
      pos 5418
      pos 5443
      pos 5563
      pos 5572
      pos 5587
      pos 5596
      pos 5608
      pos 5610
      pos 5621
      pos 5625
      pos 5644
      pos 5647
      pos 5669
      pos 5675
      pos 5694
      pos 5699
      pos 5706
      pos 5739
      pos 5763
      pos 5776
      pos 5790
      pos 5807
      pos 5817
      pos 5852
      pos 5855
      pos 5864
      pos 5871
    doc 15
      freq 189
      pos 45
      pos 68
      pos 100
      pos 106
      pos 139
      pos 163
      pos 169
      pos 313
      pos 317
      pos 338
      pos 345
      pos 506
      pos 540
      pos 573
      pos 616
      pos 652
      pos 661
      pos 717
      pos 727
      pos 733
      pos 736
      pos 742
      pos 750
      pos 784
      pos 795
      pos 808
      pos 842
      pos 861
      pos 896
      pos 899
      pos 908
      pos 921
      pos 993
      pos 1086
      pos 1091
      pos 1097
      pos 1109
      pos 1119
      pos 1150
      pos 1153
      pos 1184
      pos 1187
      pos 1191
      pos 1224
      pos 1324
      pos 1327
      pos 1341
      pos 1355
      pos 1367
      pos 1400
      pos 1405
      pos 1411
      pos 1429
      pos 1442
      pos 1454
      pos 1457
      pos 1462
      pos 1488
      pos 1554
      pos 1576
      pos 1610
      pos 1700
      pos 1765
      pos 1772
      pos 1776
      pos 1787
      pos 1805
      pos 1846
      pos 1850
      pos 1854
      pos 1899
      pos 1931
      pos 1958
      pos 1982
      pos 1986
      pos 1991
      pos 1999
      pos 2059
      pos 2071
      pos 2093
      pos 2101
      pos 2108
      pos 2125
      pos 2131
      pos 2135
      pos 2156
      pos 2159
      pos 2205
      pos 2220
      pos 2276
      pos 2288
      pos 2312
      pos 2428
      pos 2470
      pos 2479
      pos 2514
      pos 2577
      pos 2584
      pos 2626
      pos 2681
      pos 2706
      pos 2742
      pos 2781
      pos 2789
      pos 2820
      pos 2831
      pos 2839
      pos 2843
      pos 2848
      pos 2865
      pos 2870
      pos 2878
      pos 2883
      pos 2900
      pos 2909
      pos 2916
      pos 2920
      pos 2936
      pos 2943
      pos 2959
      pos 2972
      pos 2987
      pos 2994
      pos 3025
      pos 3032
      pos 3042
      pos 3122
      pos 3151
      pos 3159
      pos 3174
      pos 3179
      pos 3183
      pos 3215
      pos 3234
      pos 3255
      pos 3301
      pos 3424
      pos 3455
      pos 3460
      pos 3466
      pos 3473
      pos 3495
      pos 3500
      pos 3504
      pos 3536
      pos 3579
      pos 3582
      pos 3596
      pos 3599
      pos 3608
      pos 3629
      pos 3671
      pos 3684
      pos 3688
      pos 3739
      pos 3775
      pos 3786
      pos 3791
      pos 3832
      pos 3835
      pos 3864
      pos 3871
      pos 3878
      pos 3887
      pos 4082
      pos 4091
      pos 4106
      pos 4115
      pos 4127
      pos 4129
      pos 4140
      pos 4144
      pos 4163
      pos 4166
      pos 4188
      pos 4194
      pos 4213
      pos 4218
      pos 4225
      pos 4258
      pos 4282
      pos 4295
      pos 4309
      pos 4326
      pos 4336
      pos 4371
      pos 4374
      pos 4383
      pos 4390
    doc 16
      freq 209
      pos 39
      pos 52
      pos 56
      pos 64
      pos 82
      pos 87
      pos 91
      pos 98
      pos 108
      pos 128
      pos 133
      pos 152
      pos 160
      pos 176
      pos 180
      pos 188
      pos 195
      pos 200
      pos 212
      pos 224
      pos 226
      pos 230
      pos 241
      pos 263
      pos 269
      pos 273
      pos 279
      pos 282
      pos 289
      pos 307
      pos 310
      pos 343
      pos 370
      pos 381
      pos 385
      pos 388
      pos 402
      pos 408
      pos 412
      pos 417
      pos 463
      pos 469
      pos 472
      pos 500
      pos 504
      pos 508
      pos 522
      pos 525
      pos 541
      pos 547
      pos 553
      pos 556
      pos 628
      pos 633
      pos 644
      pos 647
      pos 650
      pos 659
      pos 662
      pos 671
      pos 676
      pos 684
      pos 688
      pos 699
      pos 716
      pos 739
      pos 751
      pos 754
      pos 767
      pos 770
      pos 782
      pos 795
      pos 799
      pos 805
      pos 816
      pos 822
      pos 826
      pos 830
      pos 844
      pos 848
      pos 853
      pos 856
      pos 870
      pos 875
      pos 900
      pos 917
      pos 928
      pos 932
      pos 939
      pos 943
      pos 948
      pos 951
      pos 963
      pos 967
      pos 973
      pos 979
      pos 998
      pos 1024
      pos 1031
      pos 1058
      pos 1066
      pos 1071
      pos 1096
      pos 1102
      pos 1109
      pos 1125
      pos 1130
      pos 1134
      pos 1141
      pos 1167
      pos 1174
      pos 1183
      pos 1186
      pos 1200
      pos 1217
      pos 1222
      pos 1245
      pos 1250
      pos 1257
      pos 1264
      pos 1285
      pos 1290
      pos 1298
      pos 1304
      pos 1323
      pos 1330
      pos 1335
      pos 1347
      pos 1360
      pos 1383
      pos 1387
      pos 1394
      pos 1399
      pos 1412
      pos 1417
      pos 1433
      pos 1437
      pos 1458
      pos 1468
      pos 1536
      pos 1539
      pos 1544
      pos 1549
      pos 1579
      pos 1582
      pos 1595
      pos 1600
      pos 1614
      pos 1619
      pos 1630
      pos 1655
      pos 1669
      pos 1673
      pos 1680
      pos 1707
      pos 1710
      pos 1722
      pos 1743
      pos 1760
      pos 1766
      pos 1864
      pos 1869
      pos 1889
      pos 1898
      pos 1902
      pos 1910
      pos 1914
      pos 1918
      pos 1925
      pos 1930
      pos 2049
      pos 2122
      pos 2127
      pos 2149
      pos 2259
      pos 2267
      pos 2270
      pos 2279
      pos 2289
      pos 2382
      pos 2472
      pos 2477
      pos 2488
      pos 2503
      pos 2693
      pos 2702
      pos 2717
      pos 2726
      pos 2738
      pos 2740
      pos 2751
      pos 2755
      pos 2774
      pos 2777
      pos 2799
      pos 2805
      pos 2824
      pos 2829
      pos 2836
      pos 2869
      pos 2893
      pos 2906
      pos 2920
      pos 2937
      pos 2947
      pos 2982
      pos 2985
      pos 2994
      pos 3001
    doc 17
      freq 185
      pos 36
      pos 49
      pos 53
      pos 61
      pos 79
      pos 93
      pos 106
      pos 139
      pos 184
      pos 219
      pos 221
      pos 239
      pos 250
      pos 266
      pos 311
      pos 333
      pos 370
      pos 376
      pos 381
      pos 404
      pos 422
      pos 426
      pos 429
      pos 437
      pos 455
      pos 468
      pos 473
      pos 483
      pos 490
      pos 498
      pos 546
      pos 558
      pos 563
      pos 567
      pos 596
      pos 604
      pos 609
      pos 624
      pos 628
      pos 631
      pos 635
      pos 646
      pos 651
      pos 657
      pos 666
      pos 673
      pos 677
      pos 685
      pos 691
      pos 697
      pos 704
      pos 710
      pos 713
      pos 719
      pos 728
      pos 732
      pos 738
      pos 751
      pos 762
      pos 768
      pos 778
      pos 781
      pos 958
      pos 971
      pos 978
      pos 996
      pos 1000
      pos 1004
      pos 1010
      pos 1026
      pos 1028
      pos 1032
      pos 1059
      pos 1077
      pos 1082
      pos 1087
      pos 1089
      pos 1102
      pos 1106
      pos 1109
      pos 1134
      pos 1145
      pos 1154
      pos 1160
      pos 1162
      pos 1166
      pos 1170
      pos 1180
      pos 1184
      pos 1196
      pos 1201
      pos 1203
      pos 1218
      pos 1226
      pos 1231
      pos 1236
      pos 1241
      pos 1251
      pos 1261
      pos 1268
      pos 1271
      pos 1289
      pos 1298
      pos 1310
      pos 1315
      pos 1321
      pos 1349
      pos 1361
      pos 1376
      pos 1389
      pos 1439
      pos 1442
      pos 1447
      pos 1450
      pos 1504
      pos 1519
      pos 1526
      pos 1532
      pos 1536
      pos 1540
      pos 1560
      pos 1563
      pos 1575
      pos 1584
      pos 1613
      pos 1616
      pos 1620
      pos 1629
      pos 1633
      pos 1638
      pos 1650
      pos 1659
      pos 1670
      pos 1696
      pos 1700
      pos 1704
      pos 1708
      pos 1717
      pos 1723
      pos 1738
      pos 1746
      pos 1751
      pos 1761
      pos 1773
      pos 1783
      pos 1795
      pos 1799
      pos 1813
      pos 1821
      pos 1827
      pos 1866
      pos 1897
      pos 1945
      pos 1956
      pos 1959
      pos 1974
      pos 1977
      pos 1985
      pos 2019
      pos 2135
      pos 2417
      pos 2426
      pos 2441
      pos 2450
      pos 2462
      pos 2464
      pos 2475
      pos 2479
      pos 2498
      pos 2501
      pos 2523
      pos 2529
      pos 2548
      pos 2553
      pos 2560
      pos 2593
      pos 2617
      pos 2630
      pos 2644
      pos 2661
      pos 2671
      pos 2706
      pos 2709
      pos 2718
      pos 2725
    doc 18
      freq 143
      pos 45
      pos 58
      pos 62
      pos 70
      pos 88
      pos 130
      pos 140
      pos 192
      pos 205
      pos 208
      pos 213
      pos 216
      pos 230
      pos 265
      pos 268
      pos 275
      pos 292
      pos 368
      pos 371
      pos 382
      pos 416
      pos 448
      pos 495
      pos 498
      pos 509
      pos 515
      pos 539
      pos 550
      pos 556
      pos 596
      pos 628
      pos 640
      pos 645
      pos 654
      pos 660
      pos 665
      pos 669
      pos 680
      pos 689
      pos 694
      pos 699
      pos 724
      pos 748
      pos 763
      pos 773
      pos 787
      pos 794
      pos 802
      pos 818
      pos 837
      pos 841
      pos 845
      pos 858
      pos 874
      pos 887
      pos 891
      pos 901
      pos 906
      pos 918
      pos 927
      pos 931
      pos 953
      pos 978
      pos 985
      pos 990
      pos 993
      pos 996
      pos 1000
      pos 1003
      pos 1048
      pos 1056
      pos 1075
      pos 1080
      pos 1086
      pos 1102
      pos 1115
      pos 1129
      pos 1146
      pos 1166
      pos 1180
      pos 1194
      pos 1233
      pos 1257
      pos 1297
      pos 1301
      pos 1327
      pos 1336
      pos 1343
      pos 1365
      pos 1376
      pos 1529
      pos 1544
      pos 1583
      pos 1593
      pos 1610
      pos 1614
      pos 1626
      pos 1696
      pos 1714
      pos 1784
      pos 1799
      pos 1802
      pos 1828
      pos 1838
      pos 1853
      pos 1868
      pos 1872
      pos 1896
      pos 1909
      pos 1941
      pos 1966
      pos 1972
      pos 1975
      pos 2008
      pos 2036
      pos 2054
      pos 2095
      pos 2118
      pos 2205
      pos 2214
      pos 2229
      pos 2238
      pos 2250
      pos 2252
      pos 2263
      pos 2267
      pos 2286
      pos 2289
      pos 2311
      pos 2317
      pos 2336
      pos 2341
      pos 2348
      pos 2381
      pos 2405
      pos 2418
      pos 2432
      pos 2449
      pos 2459
      pos 2494
      pos 2497
      pos 2506
      pos 2513
    skipList 
      level 0
        skipDoc 7
        skipDocFP 2275639
        impacts 
          impact 
            freq 154
            norm 100
          impact 
            freq 206
            norm 101
          impact 
            freq 328
            norm 104
          impact 
            freq 434
            norm 107
          impact 
            freq 437
            norm 108
          impact 
            freq 725
            norm 113
          impact 
            freq 836
            norm 120
        impactsEnd 
        skipDoc 15
        skipDocFP 2327794
        impacts 
          impact 
            freq 135
            norm 95
          impact 
            freq 189
            norm 104
          impact 
            freq 278
            norm 107
          impact 
            freq 294
            norm 109
          impact 
            freq 576
            norm 113
          impact 
            freq 954
            norm 116
        impactsEnd 
  term their
    doc 0
      freq 2
      pos 16073
      pos 17256
    doc 1
      freq 3
      pos 4821
      pos 5039
      pos 9637
    doc 2
      freq 11
      pos 872
      pos 1397
      pos 1631
      pos 1816
      pos 3906
      pos 4228
      pos 4422
      pos 5370
      pos 5388
      pos 5413
      pos 6434
    doc 3
      freq 2
      pos 477
      pos 5986
    doc 4
      freq 5
      pos 710
      pos 2336
      pos 4127
      pos 5668
      pos 6141
    doc 5
      freq 6
      pos 878
      pos 3236
      pos 3824
      pos 4098
      pos 4103
      pos 4471
    doc 6
      freq 2
      pos 2717
      pos 3271
    doc 7
      freq 1
      pos 2976
    doc 8
      freq 1
      pos 2193
    doc 9
      freq 1
      pos 1838
    doc 10
      freq 22
      pos 988
      pos 1228
      pos 1637
      pos 2203
      pos 5297
      pos 5968
      pos 6125
      pos 6173
      pos 7628
      pos 8937
      pos 9201
      pos 9207
      pos 9221
      pos 9841
      pos 9978
      pos 10441
      pos 10892
      pos 11493
      pos 12137
      pos 12922
      pos 12943
      pos 13499
    doc 11
      freq 7
      pos 2064
      pos 4754
      pos 4962
      pos 9339
      pos 9504
      pos 9515
      pos 10660
    doc 12
      freq 3
      pos 4705
      pos 5471
      pos 9510
    doc 13
      freq 12
      pos 418
      pos 989
      pos 2135
      pos 3503
      pos 3864
      pos 4402
      pos 4774
      pos 5806
      pos 6435
      pos 6537
      pos 6979
      pos 7125
    doc 14
      freq 3
      pos 636
      pos 5353
      pos 5591
    doc 15
      freq 3
      pos 1594
      pos 3078
      pos 4110
    doc 16
      freq 2
      pos 1587
      pos 2721
    doc 17
      freq 2
      pos 1410
      pos 2445
    doc 18
      freq 2
      pos 2050
      pos 2233
    skipList 
      level 0
        skipDoc 7
        skipDocFP 2379055
        impacts 
          impact 
            freq 1
            norm 100
          impact 
            freq 2
            norm 101
          impact 
            freq 6
            norm 104
          impact 
            freq 11
            norm 108
        impactsEnd 
        skipDoc 15
        skipDocFP 2379718
        impacts 
          impact 
            freq 1
            norm 95
          impact 
            freq 3
            norm 104
          impact 
            freq 12
            norm 109
          impact 
            freq 22
            norm 116
        impactsEnd 
  term them
    doc 0
      freq 2
      pos 14022
      pos 16881
    doc 1
      freq 1
      pos 136
    doc 2
      freq 2
      pos 3916
      pos 4161
    doc 3
      freq 2
      pos 1114
      pos 1212
    doc 4
      freq 1
      pos 4623
    doc 7
      freq 1
      pos 648
    doc 10
      freq 2
      pos 1233
      pos 2198
    doc 11
      freq 2
      pos 871
      pos 4843
    doc 12
      freq 4
      pos 2417
      pos 4258
      pos 6966
      pos 9170
    doc 13
      freq 3
      pos 2799
      pos 5694
      pos 6456
    doc 15
      freq 1
      pos 2667
    doc 16
      freq 4
      pos 218
      pos 221
      pos 277
      pos 638
    doc 17
      freq 1
      pos 1420
    doc 18
      freq 1
      pos 1679
    skipList 
      level 0
        skipDoc 11
        skipDocFP 2381525
        impacts 
          impact 
            freq 1
            norm 100
          impact 
            freq 2
            norm 107
        impactsEnd 
  term themselves
    doc 1
      freq 2
      pos 8292
      pos 8334
    doc 4
      freq 1
      pos 4552
    doc 5
      freq 1
      pos 3014
    doc 10
      freq 5
      pos 472
      pos 559
      pos 898
      pos 3963
      pos 9259
    doc 12
      freq 1
      pos 4712
    doc 17
      freq 2
      pos 253
      pos 1276
  term then
    doc 0
      freq 20
      pos 2992
      pos 3637
      pos 3830
      pos 3857
      pos 4153
      pos 4330
      pos 4357
      pos 5276
      pos 5309
      pos 5334
      pos 5345
      pos 6760
      pos 10995
      pos 11194
      pos 11221
      pos 14792
      pos 15861
      pos 16184
      pos 16770
      pos 16823
    doc 1
      freq 19
      pos 1616
      pos 1642
      pos 2601
      pos 3506
      pos 3537
      pos 3835
      pos 4535
      pos 4705
      pos 4943
      pos 5665
      pos 5770
      pos 5894
      pos 5933
      pos 6405
      pos 6477
      pos 6521
      pos 6577
      pos 6625
      pos 6690
    doc 2
      freq 5
      pos 4226
      pos 4462
      pos 4552
      pos 4791
      pos 5526
    doc 3
      freq 3
      pos 2307
      pos 2413
      pos 5402
    doc 5
      freq 3
      pos 997
      pos 3457
      pos 3583
    doc 6
      freq 3
      pos 651
      pos 1879
      pos 2668
    doc 7
      freq 1
      pos 609
    doc 9
      freq 4
      pos 696
      pos 858
      pos 1466
      pos 1505
    doc 10
      freq 14
      pos 1212
      pos 1302
      pos 1836
      pos 1905
      pos 2983
      pos 3605
      pos 3887
      pos 4055
      pos 4234
      pos 5268
      pos 6706
      pos 6740
      pos 7385
      pos 10084
    doc 11
      freq 1
      pos 7490
    doc 12
      freq 2
      pos 3467
      pos 6677
    doc 13
      freq 3
      pos 436
      pos 1084
      pos 2625
    doc 14
      freq 8
      pos 835
      pos 1037
      pos 1058
      pos 1528
      pos 1689
      pos 1710
      pos 2210
      pos 2624
    doc 15
      freq 11
      pos 1095
      pos 1221
      pos 1409
      pos 1459
      pos 1952
      pos 2217
      pos 2454
      pos 2494
      pos 2685
      pos 3385
      pos 3497
    doc 16
      freq 2
      pos 155
      pos 467
    doc 17
      freq 6
      pos 650
      pos 712
      pos 1244
      pos 1385
      pos 1446
      pos 1750
    doc 18
      freq 1
      pos 1304
    skipList 
      level 0
        skipDoc 9
        skipDocFP 2382828
        impacts 
          impact 
            freq 4
            norm 95
          impact 
            freq 5
            norm 108
          impact 
            freq 19
            norm 113
          impact 
            freq 20
            norm 120
        impactsEnd 
        skipDoc 17
        skipDocFP 2383887
        impacts 
          impact 
            freq 6
            norm 98
          impact 
            freq 11
            norm 104
          impact 
            freq 14
            norm 116
        impactsEnd 
  term theory
    doc 15
      freq 1
      pos 3436
  term there
    doc 0
      freq 22
      pos 369
      pos 5385
      pos 11262
      pos 12888
      pos 12974
      pos 13142
      pos 13244
      pos 13461
      pos 13559
      pos 13651
      pos 13753
      pos 13826
      pos 13898
      pos 14038
      pos 14111
      pos 14167
      pos 14401
      pos 14423
      pos 14567
      pos 14589
      pos 16091
      pos 16771
    doc 1
      freq 11
      pos 1217
      pos 1935
      pos 2612
      pos 2620
      pos 3848
      pos 5196
      pos 6433
      pos 7483
      pos 7502
      pos 8041
      pos 8245
    doc 2
      freq 6
      pos 4165
      pos 4185
      pos 4322
      pos 4637
      pos 4827
      pos 5395
    doc 3
      freq 3
      pos 677
      pos 5232
      pos 5818
    doc 4
      freq 3
      pos 897
      pos 1670
      pos 3999
    doc 5
      freq 1
      pos 452
    doc 6
      freq 6
      pos 75
      pos 100
      pos 299
      pos 450
      pos 1880
      pos 2070
    doc 7
      freq 4
      pos 501
      pos 542
      pos 1414
      pos 1475
    doc 9
      freq 4
      pos 473
      pos 859
      pos 1393
      pos 1570
    doc 10
      freq 16
      pos 1401
      pos 2790
      pos 4278
      pos 5188
      pos 7186
      pos 7825
      pos 9099
      pos 9517
      pos 9590
      pos 9622
      pos 9895
      pos 9957
      pos 10264
      pos 10879
      pos 11092
      pos 11289
    doc 11
      freq 9
      pos 917
      pos 1801
      pos 1829
      pos 2628
      pos 6328
      pos 9178
      pos 9192
      pos 9212
      pos 9234
    doc 12
      freq 19
      pos 962
      pos 1236
      pos 1433
      pos 1673
      pos 1854
      pos 1969
      pos 2018
      pos 2996
      pos 3119
      pos 3173
      pos 3231
      pos 3356
      pos 3933
      pos 5578
      pos 6323
      pos 6436
      pos 8119
      pos 8428
      pos 8462
    doc 13
      freq 9
      pos 1689
      pos 2040
      pos 2059
      pos 2511
      pos 2790
      pos 2844
      pos 3008
      pos 3084
      pos 4099
    doc 14
      freq 1
      pos 2563
    doc 15
      freq 24
      pos 433
      pos 459
      pos 972
      pos 1143
      pos 1492
      pos 1690
      pos 2045
      pos 2076
      pos 2118
      pos 2254
      pos 2317
      pos 2503
      pos 2523
      pos 2645
      pos 2720
      pos 2730
      pos 2799
      pos 3055
      pos 3227
      pos 3261
      pos 3275
      pos 3356
      pos 3398
      pos 3811
    doc 16
      freq 1
      pos 301
    doc 17
      freq 1
      pos 1777
    doc 18
      freq 3
      pos 1548
      pos 1771
      pos 1950
    skipList 
      level 0
        skipDoc 7
        skipDocFP 2385485
        impacts 
          impact 
            freq 4
            norm 100
          impact 
            freq 6
            norm 101
          impact 
            freq 11
            norm 113
          impact 
            freq 22
            norm 120
        impactsEnd 
        skipDoc 16
        skipDocFP 2386520
        impacts 
          impact 
            freq 4
            norm 95
          impact 
            freq 24
            norm 104
        impactsEnd 
  term there's
    doc 11
      freq 3
      pos 4400
      pos 6578
      pos 8356
  term thereby
    doc 10
      freq 1
      pos 9005
  term therefor
    doc 1
      freq 4
      pos 5849
      pos 7973
      pos 8475
      pos 8580
    doc 2
      freq 1
      pos 1145
    doc 3
      freq 4
      pos 3092
      pos 3524
      pos 4096
      pos 5809
    doc 4
      freq 2
      pos 4282
      pos 4687
    doc 6
      freq 2
      pos 1429
      pos 2856
    doc 7
      freq 1
      pos 1717
    doc 10
      freq 5
      pos 5315
      pos 6098
      pos 6301
      pos 6940
      pos 7678
    doc 12
      freq 3
      pos 1200
      pos 3093
      pos 9247
    doc 13
      freq 1
      pos 2034
    doc 16
      freq 1
      pos 2484
    doc 17
      freq 1
      pos 1277
    skipList 
      level 0
        skipDoc 12
        skipDocFP 2388758
        impacts 
          impact 
            freq 1
            norm 100
          impact 
            freq 2
            norm 101
          impact 
            freq 4
            norm 107
          impact 
            freq 5
            norm 116
        impactsEnd 
  term therein
    doc 0
      freq 1
      pos 17251
    doc 1
      freq 1
      pos 9632
    doc 2
      freq 1
      pos 6429
    doc 3
      freq 1
      pos 5981
    doc 4
      freq 1
      pos 6136
    doc 5
      freq 1
      pos 4466
    doc 6
      freq 1
      pos 3266
    doc 7
      freq 1
      pos 2971
    doc 8
      freq 1
      pos 2188
    doc 9
      freq 1
      pos 1833
    doc 10
      freq 1
      pos 13494
    doc 11
      freq 1
      pos 10655
    doc 12
      freq 1
      pos 9505
    doc 13
      freq 1
      pos 7120
    doc 14
      freq 1
      pos 5586
    doc 15
      freq 1
      pos 4105
    doc 16
      freq 1
      pos 2716
    doc 17
      freq 1
      pos 2440
    doc 18
      freq 1
      pos 2228
    skipList 
      level 0
        skipDoc 7
        skipDocFP 2389748
        impacts 
          impact 
            freq 1
            norm 100
        impactsEnd 
        skipDoc 15
        skipDocFP 2390053
        impacts 
          impact 
            freq 1
            norm 95
        impactsEnd 
  term thereof
    doc 1
      freq 1
      pos 3293
    doc 8
      freq 1
      pos 292
  term these
    doc 0
      freq 12
      pos 1680
      pos 3008
      pos 7857
      pos 8378
      pos 8407
      pos 9021
      pos 13038
      pos 16277
      pos 16364
      pos 16385
      pos 16450
      pos 16492
    doc 1
      freq 9
      pos 782
      pos 2163
      pos 3484
      pos 3738
      pos 3792
      pos 6191
      pos 6310
      pos 6327
      pos 8374
    doc 2
      freq 6
      pos 4209
      pos 4496
      pos 4600
      pos 4746
      pos 4900
      pos 5468
    doc 3
      freq 3
      pos 1013
      pos 1587
      pos 2646
    doc 4
      freq 5
      pos 343
      pos 352
      pos 964
      pos 4124
      pos 4650
    doc 5
      freq 4
      pos 552
      pos 567
      pos 922
      pos 3455
    doc 6
      freq 8
      pos 106
      pos 392
      pos 468
      pos 505
      pos 517
      pos 2550
      pos 2791
      pos 2854
    doc 7
      freq 3
      pos 1664
      pos 1689
      pos 1699
    doc 8
      freq 3
      pos 350
      pos 363
      pos 1522
    doc 10
      freq 20
      pos 726
      pos 812
      pos 819
      pos 978
      pos 2175
      pos 3360
      pos 4517
      pos 4778
      pos 4791
      pos 5293
      pos 5999
      pos 6170
      pos 7685
      pos 8289
      pos 8327
      pos 9264
      pos 10158
      pos 10531
      pos 11500
      pos 12906
    doc 11
      freq 11
      pos 608
      pos 787
      pos 880
      pos 889
      pos 1017
      pos 2442
      pos 5588
      pos 5606
      pos 5754
      pos 5772
      pos 7709
    doc 12
      freq 16
      pos 621
      pos 1248
      pos 1636
      pos 1718
      pos 1833
      pos 1921
      pos 2095
      pos 2339
      pos 3470
      pos 3715
      pos 3940
      pos 4397
      pos 4447
      pos 5276
      pos 8620
      pos 8730
    doc 13
      freq 10
      pos 99
      pos 489
      pos 1105
      pos 1557
      pos 1642
      pos 1697
      pos 1952
      pos 2079
      pos 4436
      pos 4445
    doc 14
      freq 4
      pos 86
      pos 620
      pos 668
      pos 2599
    doc 15
      freq 5
      pos 363
      pos 494
      pos 1838
      pos 2170
      pos 3876
    doc 16
      freq 1
      pos 1625
    doc 18
      freq 9
      pos 120
      pos 315
      pos 342
      pos 714
      pos 1040
      pos 1053
      pos 1370
      pos 1532
      pos 1556
    skipList 
      level 0
        skipDoc 7
        skipDocFP 2390891
        impacts 
          impact 
            freq 3
            norm 100
          impact 
            freq 8
            norm 101
          impact 
            freq 9
            norm 113
          impact 
            freq 12
            norm 120
        impactsEnd 
        skipDoc 16
        skipDocFP 2391820
        impacts 
          impact 
            freq 3
            norm 97
          impact 
            freq 5
            norm 104
          impact 
            freq 10
            norm 109
          impact 
            freq 16
            norm 113
          impact 
            freq 20
            norm 116
        impactsEnd 
  term they
    doc 0
      freq 14
      pos 753
      pos 971
      pos 12020
      pos 12905
      pos 13159
      pos 13261
      pos 13478
      pos 13576
      pos 13668
      pos 13770
      pos 13843
      pos 13915
      pos 14055
      pos 14184
    doc 1
      freq 4
      pos 2882
      pos 4918
      pos 5354
      pos 6130
    doc 3
      freq 2
      pos 3703
      pos 4165
    doc 4
      freq 4
      pos 843
      pos 4543
      pos 5634
      pos 5664
    doc 6
      freq 1
      pos 475
    doc 7
      freq 1
      pos 667
    doc 8
      freq 1
      pos 294
    doc 10
      freq 14
      pos 601
      pos 732
      pos 1645
      pos 1647
      pos 2299
      pos 2314
      pos 3754
      pos 4029
      pos 4520
      pos 5215
      pos 9209
      pos 9310
      pos 9313
      pos 12856
    doc 11
      freq 8
      pos 710
      pos 1819
      pos 1883
      pos 3259
      pos 4616
      pos 4846
      pos 5284
      pos 7596
    doc 12
      freq 10
      pos 641
      pos 1195
      pos 1311
      pos 4648
      pos 4700
      pos 4719
      pos 5476
      pos 5524
      pos 6881
      pos 8218
    doc 13
      freq 6
      pos 1536
      pos 2189
      pos 2470
      pos 2656
      pos 3616
      pos 4110
    doc 14
      freq 1
      pos 1925
    doc 16
      freq 1
      pos 2480
    doc 17
      freq 2
      pos 1323
      pos 1684
    doc 18
      freq 2
      pos 1560
      pos 2003
    skipList 
      level 0
        skipDoc 10
        skipDocFP 2393932
        impacts 
          impact 
            freq 1
            norm 97
          impact 
            freq 2
            norm 107
          impact 
            freq 4
            norm 108
          impact 
            freq 14
            norm 116
        impactsEnd 
  term thing
    doc 12
      freq 1
      pos 6049
  term things
    doc 6
      freq 1
      pos 129
    doc 12
      freq 1
      pos 3234
  term thinking
    doc 11
      freq 1
      pos 9395
  term third
    doc 1
      freq 1
      pos 8343
    doc 7
      freq 1
      pos 1626
    doc 9
      freq 1
      pos 443
    doc 10
      freq 2
      pos 2885
      pos 5372
    doc 11
      freq 3
      pos 955
      pos 963
      pos 974
    doc 12
      freq 5
      pos 646
      pos 3822
      pos 4863
      pos 6447
      pos 7597
  term this
    doc 0
      freq 350
      pos 30
      pos 32
      pos 72
      pos 76
      pos 89
      pos 111
      pos 267
      pos 301
      pos 385
      pos 426
      pos 463
      pos 494
      pos 517
      pos 528
      pos 549
      pos 573
      pos 588
      pos 609
      pos 623
      pos 641
      pos 731
      pos 745
      pos 761
      pos 779
      pos 798
      pos 837
      pos 861
      pos 873
      pos 894
      pos 917
      pos 936
      pos 974
      pos 1122
      pos 1156
      pos 1168
      pos 1215
      pos 1218
      pos 1444
      pos 1833
      pos 2107
      pos 2201
      pos 2224
      pos 2250
      pos 2272
      pos 2349
      pos 2364
      pos 2397
      pos 2400
      pos 2422
      pos 2492
      pos 2507
      pos 2561
      pos 2564
      pos 2687
      pos 2736
      pos 2740
      pos 2828
      pos 2877
      pos 2917
      pos 2958
      pos 2967
      pos 2985
      pos 3053
      pos 3077
      pos 3153
      pos 3191
      pos 3203
      pos 3262
      pos 3274
      pos 3283
      pos 3292
      pos 3308
      pos 3345
      pos 3382
      pos 3432
      pos 3507
      pos 3545
      pos 3643
      pos 3710
      pos 3732
      pos 3756
      pos 3788
      pos 3894
      pos 3915
      pos 3938
      pos 3945
      pos 3969
      pos 3976
      pos 4025
      pos 4159
      pos 4222
      pos 4244
      pos 4250
      pos 4300
      pos 4394
      pos 4427
      pos 4574
      pos 4637
      pos 4747
      pos 4773
      pos 4777
      pos 4779
      pos 4794
      pos 4847
      pos 4850
      pos 4879
      pos 4892
      pos 4904
      pos 4997
      pos 5007
      pos 5050
      pos 5061
      pos 5072
      pos 5160
      pos 5190
      pos 5214
      pos 5249
      pos 5277
      pos 5306
      pos 5353
      pos 5424
      pos 5453
      pos 5527
      pos 5534
      pos 5552
      pos 5572
      pos 5609
      pos 5612
      pos 5659
      pos 5677
      pos 5711
      pos 5744
      pos 5813
      pos 5846
      pos 5890
      pos 5915
      pos 5964
      pos 6067
      pos 6111
      pos 6199
      pos 6235
      pos 6253
      pos 6261
      pos 6322
      pos 6393
      pos 6414
      pos 6417
      pos 6456
      pos 6459
      pos 6487
      pos 6545
      pos 6548
      pos 6576
      pos 6586
      pos 6637
      pos 6685
      pos 6738
      pos 6741
      pos 6747
      pos 6790
      pos 6823
      pos 6860
      pos 6882
      pos 6913
      pos 6953
      pos 6960
      pos 7004
      pos 7041
      pos 7043
      pos 7061
      pos 7126
      pos 7133
      pos 7135
      pos 7176
      pos 7178
      pos 7217
      pos 7298
      pos 7403
      pos 7436
      pos 7698
      pos 7764
      pos 7793
      pos 7918
      pos 7943
      pos 7981
      pos 7985
      pos 8026
      pos 8073
      pos 8115
      pos 8168
      pos 8231
      pos 8234
      pos 8243
      pos 8437
      pos 8440
      pos 8458
      pos 8461
      pos 8505
      pos 8508
      pos 8526
      pos 8563
      pos 8566
      pos 8583
      pos 8621
      pos 8624
      pos 8653
      pos 8656
      pos 8678
      pos 8681
      pos 8698
      pos 8701
      pos 8723
      pos 8726
      pos 8743
      pos 8746
      pos 8768
      pos 8786
      pos 8808
      pos 8868
      pos 8947
      pos 8949
      pos 9196
      pos 9265
      pos 9267
      pos 9408
      pos 9516
      pos 9607
      pos 9695
      pos 9704
      pos 9777
      pos 9832
      pos 10085
      pos 10087
      pos 10119
      pos 10122
      pos 10146
      pos 10183
      pos 10208
      pos 10211
      pos 10216
      pos 10270
      pos 10274
      pos 10354
      pos 10409
      pos 10486
      pos 10488
      pos 10522
      pos 10573
      pos 10695
      pos 10779
      pos 10875
      pos 11001
      pos 11083
      pos 11116
      pos 11120
      pos 11133
      pos 11326
      pos 11331
      pos 11363
      pos 11392
      pos 11415
      pos 11419
      pos 11445
      pos 11471
      pos 11516
      pos 11518
      pos 11548
      pos 11580
      pos 11582
      pos 11622
      pos 11626
      pos 11683
      pos 11812
      pos 11835
      pos 11857
      pos 11886
      pos 11891
      pos 11913
      pos 11937
      pos 11956
      pos 12138
      pos 12188
      pos 12210
      pos 12229
      pos 12248
      pos 12271
      pos 12326
      pos 12348
      pos 12352
      pos 12560
      pos 12562
      pos 12621
      pos 12696
      pos 12711
      pos 12795
      pos 12812
      pos 12834
      pos 12846
      pos 12867
      pos 12899
      pos 12927
      pos 12949
      pos 13030
      pos 13032
      pos 13050
      pos 13098
      pos 13153
      pos 13212
      pos 13255
      pos 13298
      pos 13374
      pos 13399
      pos 13429
      pos 13472
      pos 13515
      pos 13570
      pos 13619
      pos 13662
      pos 13709
      pos 13764
      pos 13837
      pos 13909
      pos 14049
      pos 14098
      pos 14178
      pos 14259
      pos 14444
      pos 14531
      pos 14610
      pos 14745
      pos 14767
      pos 14812
      pos 14815
      pos 15813
      pos 15839
      pos 15862
      pos 15983
      pos 15995
      pos 16100
      pos 16330
      pos 16430
      pos 16584
      pos 16618
      pos 16796
      pos 16852
      pos 17232
      pos 17258
      pos 17368
      pos 17466
      pos 17513
    doc 1
      freq 93
      pos 47
      pos 49
      pos 89
      pos 93
      pos 165
      pos 546
      pos 648
      pos 703
      pos 726
      pos 958
      pos 960
      pos 992
      pos 1116
      pos 1176
      pos 1450
      pos 1468
      pos 1662
      pos 1733
      pos 1769
      pos 1805
      pos 1817
      pos 1828
      pos 1890
      pos 1898
      pos 1972
      pos 1986
      pos 2048
      pos 2140
      pos 2269
      pos 2276
      pos 2429
      pos 2557
      pos 2566
      pos 2597
      pos 2767
      pos 3137
      pos 3320
      pos 3600
      pos 3702
      pos 3831
      pos 3846
      pos 3948
      pos 4057
      pos 4268
      pos 4341
      pos 4612
      pos 4757
      pos 4866
      pos 4933
      pos 5004
      pos 5042
      pos 5321
      pos 5361
      pos 5401
      pos 5410
      pos 5479
      pos 5570
      pos 5572
      pos 5586
      pos 5628
      pos 5674
      pos 5971
      pos 6149
      pos 6178
      pos 6195
      pos 6220
      pos 6242
      pos 6349
      pos 6440
      pos 6442
      pos 6847
      pos 6887
      pos 7006
      pos 7031
      pos 7134
      pos 7253
      pos 7255
      pos 7267
      pos 7447
      pos 7607
      pos 7654
      pos 7747
      pos 7797
      pos 7901
      pos 7930
      pos 8069
      pos 8650
      pos 8817
      pos 9613
      pos 9639
      pos 9749
      pos 9847
      pos 9894
    doc 2
      freq 38
      pos 24
      pos 26
      pos 46
      pos 86
      pos 188
      pos 237
      pos 303
      pos 473
      pos 634
      pos 877
      pos 1320
      pos 1645
      pos 1705
      pos 1779
      pos 1976
      pos 3480
      pos 3763
      pos 3856
      pos 4304
      pos 4339
      pos 4538
      pos 4782
      pos 4949
      pos 5086
      pos 5339
      pos 5372
      pos 5611
      pos 5770
      pos 5811
      pos 5951
      pos 5990
      pos 6152
      pos 6346
      pos 6410
      pos 6436
      pos 6546
      pos 6644
      pos 6691
    doc 3
      freq 57
      pos 41
      pos 43
      pos 83
      pos 87
      pos 118
      pos 131
      pos 383
      pos 415
      pos 433
      pos 492
      pos 689
      pos 772
      pos 829
      pos 931
      pos 1251
      pos 1382
      pos 1499
      pos 1540
      pos 1711
      pos 1742
      pos 1818
      pos 1859
      pos 1897
      pos 1918
      pos 1935
      pos 2029
      pos 2054
      pos 2077
      pos 2100
      pos 2246
      pos 2355
      pos 2443
      pos 2597
      pos 2603
      pos 2980
      pos 3013
      pos 3125
      pos 3139
      pos 3269
      pos 3356
      pos 3416
      pos 3445
      pos 3512
      pos 3591
      pos 4143
      pos 4172
      pos 4222
      pos 5417
      pos 5486
      pos 5578
      pos 5845
      pos 5865
      pos 5962
      pos 5988
      pos 6098
      pos 6196
      pos 6243
    doc 4
      freq 58
      pos 43
      pos 45
      pos 85
      pos 89
      pos 102
      pos 256
      pos 321
      pos 390
      pos 410
      pos 429
      pos 460
      pos 519
      pos 566
      pos 749
      pos 907
      pos 918
      pos 1234
      pos 1329
      pos 1407
      pos 1675
      pos 1744
      pos 1779
      pos 1850
      pos 1882
      pos 2050
      pos 2204
      pos 2321
      pos 2388
      pos 2610
      pos 2656
      pos 2891
      pos 3091
      pos 3158
      pos 3518
      pos 3613
      pos 3646
      pos 3916
      pos 4161
      pos 4212
      pos 4259
      pos 4297
      pos 4381
      pos 4514
      pos 4641
      pos 4760
      pos 4818
      pos 4914
      pos 5015
      pos 5037
      pos 5053
      pos 5521
      pos 5897
      pos 5937
      pos 6117
      pos 6143
      pos 6253
      pos 6351
      pos 6398
    doc 5
      freq 60
      pos 27
      pos 29
      pos 69
      pos 73
      pos 179
      pos 193
      pos 470
      pos 534
      pos 569
      pos 692
      pos 728
      pos 748
      pos 875
      pos 943
      pos 974
      pos 1008
      pos 1037
      pos 1064
      pos 1131
      pos 1181
      pos 1518
      pos 1631
      pos 1664
      pos 1687
      pos 1721
      pos 1752
      pos 1866
      pos 2169
      pos 2207
      pos 2217
      pos 2257
      pos 2312
      pos 2444
      pos 2476
      pos 2591
      pos 2658
      pos 2677
      pos 2804
      pos 2808
      pos 2830
      pos 2852
      pos 2885
      pos 3010
      pos 3253
      pos 3262
      pos 3279
      pos 3401
      pos 3427
      pos 3553
      pos 3580
      pos 3695
      pos 3714
      pos 3763
      pos 3936
      pos 3959
      pos 4447
      pos 4473
      pos 4583
      pos 4681
      pos 4728
    doc 6
      freq 28
      pos 27
      pos 29
      pos 49
      pos 63
      pos 88
      pos 119
      pos 149
      pos 156
      pos 176
      pos 275
      pos 522
      pos 560
      pos 611
      pos 1192
      pos 1327
      pos 1349
      pos 1488
      pos 2389
      pos 2456
      pos 2773
      pos 2813
      pos 2820
      pos 3172
      pos 3242
      pos 3273
      pos 3383
      pos 3481
      pos 3528
    doc 7
      freq 28
      pos 38
      pos 40
      pos 60
      pos 73
      pos 206
      pos 219
      pos 439
      pos 456
      pos 522
      pos 606
      pos 1149
      pos 1170
      pos 1177
      pos 1443
      pos 1449
      pos 1484
      pos 1501
      pos 1521
      pos 1541
      pos 1549
      pos 1567
      pos 1728
      pos 1766
      pos 2952
      pos 2978
      pos 3088
      pos 3186
      pos 3233
    doc 8
      freq 28
      pos 31
      pos 33
      pos 54
      pos 67
      pos 103
      pos 219
      pos 324
      pos 381
      pos 494
      pos 509
      pos 591
      pos 825
      pos 840
      pos 916
      pos 1153
      pos 1166
      pos 1241
      pos 1334
      pos 1347
      pos 1422
      pos 1537
      pos 1563
      pos 1679
      pos 2169
      pos 2195
      pos 2305
      pos 2403
      pos 2450
    doc 9
      freq 37
      pos 29
      pos 31
      pos 71
      pos 75
      pos 152
      pos 243
      pos 303
      pos 313
      pos 361
      pos 385
      pos 454
      pos 497
      pos 499
      pos 531
      pos 615
      pos 711
      pos 888
      pos 1056
      pos 1112
      pos 1180
      pos 1194
      pos 1198
      pos 1218
      pos 1252
      pos 1284
      pos 1348
      pos 1381
      pos 1490
      pos 1530
      pos 1549
      pos 1558
      pos 1560
      pos 1814
      pos 1840
      pos 1950
      pos 2048
      pos 2095
    doc 10
      freq 174
      pos 32
      pos 34
      pos 74
      pos 78
      pos 121
      pos 404
      pos 431
      pos 649
      pos 672
      pos 859
      pos 938
      pos 992
      pos 1167
      pos 1243
      pos 1330
      pos 1350
      pos 1395
      pos 1408
      pos 1454
      pos 1492
      pos 1531
      pos 1575
      pos 1581
      pos 1588
      pos 1603
      pos 1760
      pos 1777
      pos 1792
      pos 1880
      pos 1924
      pos 1970
      pos 2069
      pos 2098
      pos 2146
      pos 2165
      pos 2291
      pos 2358
      pos 2365
      pos 2458
      pos 2566
      pos 2796
      pos 2836
      pos 2907
      pos 2911
      pos 3012
      pos 3215
      pos 3317
      pos 3438
      pos 3473
      pos 3497
      pos 3506
      pos 3672
      pos 3794
      pos 3853
      pos 3939
      pos 3983
      pos 4007
      pos 4020
      pos 4068
      pos 4314
      pos 4343
      pos 4365
      pos 4503
      pos 4557
      pos 4765
      pos 5139
      pos 5182
      pos 5228
      pos 5311
      pos 5449
      pos 5480
      pos 5514
      pos 5561
      pos 5593
      pos 5643
      pos 5673
      pos 5745
      pos 5770
      pos 5850
      pos 5901
      pos 5947
      pos 6085
      pos 6121
      pos 6158
      pos 6757
      pos 7063
      pos 7158
      pos 7199
      pos 7423
      pos 7433
      pos 7468
      pos 7511
      pos 7530
      pos 7707
      pos 7711
      pos 7744
      pos 7759
      pos 7774
      pos 7931
      pos 8076
      pos 8125
      pos 8135
      pos 8193
      pos 8214
      pos 8334
      pos 8382
      pos 8396
      pos 8492
      pos 8595
      pos 8664
      pos 8814
      pos 8903
      pos 9054
      pos 9068
      pos 9116
      pos 9132
      pos 9166
      pos 9195
      pos 9277
      pos 9382
      pos 9464
      pos 9512
      pos 9536
      pos 9600
      pos 9783
      pos 9788
      pos 9870
      pos 9934
      pos 9982
      pos 10020
      pos 10046
      pos 10062
      pos 10171
      pos 10173
      pos 10196
      pos 10219
      pos 10251
      pos 10418
      pos 10583
      pos 10699
      pos 10855
      pos 10894
      pos 11001
      pos 11126
      pos 11181
      pos 11298
      pos 11311
      pos 11334
      pos 11356
      pos 11420
      pos 11423
      pos 11445
      pos 11482
      pos 11555
      pos 11599
      pos 11643
      pos 11694
      pos 11737
      pos 11795
      pos 11850
      pos 11889
      pos 11941
      pos 12023
      pos 12354
      pos 12854
      pos 12929
      pos 12950
      pos 12962
      pos 12977
      pos 13475
      pos 13501
      pos 13611
      pos 13709
      pos 13756
    doc 11
      freq 175
      pos 40
      pos 42
      pos 62
      pos 75
      pos 560
      pos 573
      pos 664
      pos 714
      pos 771
      pos 806
      pos 829
      pos 835
      pos 979
      pos 1032
      pos 1118
      pos 1204
      pos 1353
      pos 1367
      pos 1391
      pos 1409
      pos 1422
      pos 1586
      pos 1625
      pos 1746
      pos 1771
      pos 1852
      pos 1865
      pos 2009
      pos 2052
      pos 2122
      pos 2303
      pos 2322
      pos 2337
      pos 2347
      pos 2430
      pos 2473
      pos 2481
      pos 2505
      pos 2531
      pos 2615
      pos 2646
      pos 2666
      pos 2714
      pos 3210
      pos 3237
      pos 3272
      pos 3457
      pos 3483
      pos 3562
      pos 3583
      pos 3590
      pos 3698
      pos 3729
      pos 3919
      pos 3955
      pos 3966
      pos 3975
      pos 4082
      pos 4094
      pos 4110
      pos 4180
      pos 4204
      pos 4230
      pos 4250
      pos 4258
      pos 4349
      pos 4373
      pos 4389
      pos 4528
      pos 4540
      pos 4547
      pos 4566
      pos 4620
      pos 4745
      pos 4794
      pos 4855
      pos 4953
      pos 4993
      pos 5011
      pos 5083
      pos 5102
      pos 5247
      pos 5270
      pos 5407
      pos 5419
      pos 5555
      pos 5573
      pos 5716
      pos 5739
      pos 5847
      pos 5867
      pos 6036
      pos 6059
      pos 6095
      pos 6115
      pos 6260
      pos 6303
      pos 6333
      pos 6387
      pos 6404
      pos 6414
      pos 6495
      pos 6524
      pos 6551
      pos 6646
      pos 6731
      pos 6751
      pos 6802
      pos 6824
      pos 6942
      pos 6954
      pos 7005
      pos 7022
      pos 7053
      pos 7058
      pos 7152
      pos 7170
      pos 7184
      pos 7282
      pos 7297
      pos 7307
      pos 7338
      pos 7417
      pos 7443
      pos 7456
      pos 7488
      pos 7561
      pos 7588
      pos 7593
      pos 7602
      pos 7608
      pos 7677
      pos 7693
      pos 7792
      pos 7816
      pos 7831
      pos 7896
      pos 7925
      pos 7941
      pos 7968
      pos 7988
      pos 8101
      pos 8109
      pos 8246
      pos 8252
      pos 8270
      pos 8277
      pos 8296
      pos 8379
      pos 8412
      pos 8430
      pos 8439
      pos 8552
      pos 8655
      pos 8677
      pos 8692
      pos 8769
      pos 8874
      pos 8909
      pos 8970
      pos 9007
      pos 9151
      pos 9311
      pos 9362
      pos 9379
      pos 9428
      pos 9460
      pos 9512
      pos 9559
      pos 9771
      pos 10636
      pos 10662
      pos 10772
      pos 10870
      pos 10917
    doc 12
      freq 68
      pos 30
      pos 32
      pos 52
      pos 65
      pos 123
      pos 509
      pos 549
      pos 729
      pos 892
      pos 986
      pos 1478
      pos 1488
      pos 1584
      pos 1652
      pos 1781
      pos 1810
      pos 1896
      pos 2024
      pos 2125
      pos 2431
      pos 2749
      pos 2781
      pos 2983
      pos 2990
      pos 3062
      pos 3152
      pos 3209
      pos 3351
      pos 3895
      pos 3992
      pos 4035
      pos 4043
      pos 4170
      pos 4332
      pos 4405
      pos 4540
      pos 4611
      pos 4909
      pos 5389
      pos 5812
      pos 6220
      pos 6256
      pos 6495
      pos 6516
      pos 6553
      pos 6632
      pos 6691
      pos 6836
      pos 7953
      pos 7984
      pos 8067
      pos 8101
      pos 8130
      pos 8146
      pos 8525
      pos 8756
      pos 9077
      pos 9086
      pos 9093
      pos 9110
      pos 9214
      pos 9320
      pos 9364
      pos 9486
      pos 9512
      pos 9622
      pos 9720
      pos 9767
    doc 13
      freq 59
      pos 39
      pos 41
      pos 61
      pos 74
      pos 146
      pos 526
      pos 614
      pos 701
      pos 838
      pos 1026
      pos 1028
      pos 1071
      pos 1082
      pos 1108
      pos 1109
      pos 1148
      pos 1200
      pos 2037
      pos 2067
      pos 2203
      pos 2278
      pos 2309
      pos 2493
      pos 2613
      pos 2720
      pos 3441
      pos 3578
      pos 3692
      pos 3727
      pos 3759
      pos 3785
      pos 3835
      pos 3869
      pos 3943
      pos 4091
      pos 4117
      pos 4146
      pos 4240
      pos 4467
      pos 4642
      pos 4836
      pos 4872
      pos 4951
      pos 5060
      pos 5174
      pos 5233
      pos 5284
      pos 5403
      pos 5453
      pos 5637
      pos 5776
      pos 5942
      pos 6116
      pos 6985
      pos 7101
      pos 7127
      pos 7237
      pos 7335
      pos 7382
    doc 14
      freq 38
      pos 25
      pos 27
      pos 56
      pos 69
      pos 306
      pos 337
      pos 387
      pos 394
      pos 427
      pos 482
      pos 533
      pos 577
      pos 1086
      pos 1121
      pos 1159
      pos 1267
      pos 1308
      pos 1364
      pos 1466
      pos 1724
      pos 2108
      pos 2182
      pos 2423
      pos 2452
      pos 2572
      pos 2622
      pos 2651
      pos 2678
      pos 2728
      pos 2785
      pos 2812
      pos 2860
      pos 5333
      pos 5567
      pos 5593
      pos 5703
      pos 5801
      pos 5848
    doc 15
      freq 37
      pos 38
      pos 40
      pos 60
      pos 128
      pos 446
      pos 500
      pos 528
      pos 818
      pos 1015
      pos 1131
      pos 1616
      pos 1663
      pos 1687
      pos 1881
      pos 1976
      pos 2306
      pos 2340
      pos 2475
      pos 2492
      pos 2623
      pos 2653
      pos 2740
      pos 2977
      pos 2985
      pos 3016
      pos 3038
      pos 3117
      pos 3479
      pos 3723
      pos 3817
      pos 3841
      pos 3893
      pos 4086
      pos 4112
      pos 4222
      pos 4320
      pos 4367
    doc 16
      freq 21
      pos 28
      pos 30
      pos 70
      pos 74
      pos 131
      pos 415
      pos 515
      pos 1034
      pos 1042
      pos 1049
      pos 1270
      pos 1341
      pos 1666
      pos 1677
      pos 2222
      pos 2284
      pos 2697
      pos 2723
      pos 2833
      pos 2931
      pos 2978
    doc 17
      freq 30
      pos 25
      pos 27
      pos 67
      pos 71
      pos 84
      pos 109
      pos 224
      pos 264
      pos 284
      pos 617
      pos 937
      pos 982
      pos 1040
      pos 1264
      pos 1284
      pos 1293
      pos 1726
      pos 1756
      pos 1763
      pos 1803
      pos 1895
      pos 1927
      pos 1965
      pos 1990
      pos 2162
      pos 2421
      pos 2447
      pos 2557
      pos 2655
      pos 2702
    doc 18
      freq 40
      pos 34
      pos 36
      pos 76
      pos 80
      pos 93
      pos 158
      pos 221
      pos 288
      pos 298
      pos 361
      pos 399
      pos 414
      pos 488
      pos 511
      pos 553
      pos 567
      pos 574
      pos 678
      pos 701
      pos 816
      pos 869
      pos 885
      pos 1123
      pos 1240
      pos 1248
      pos 1339
      pos 1587
      pos 1638
      pos 1647
      pos 1735
      pos 1841
      pos 1957
      pos 1993
      pos 2001
      pos 2011
      pos 2209
      pos 2235
      pos 2345
      pos 2443
      pos 2490
    skipList 
      level 0
        skipDoc 7
        skipDocFP 2396251
        impacts 
          impact 
            freq 28
            norm 100
          impact 
            freq 60
            norm 104
          impact 
            freq 93
            norm 113
          impact 
            freq 350
            norm 120
        impactsEnd 
        skipDoc 15
        skipDocFP 2407087
        impacts 
          impact 
            freq 37
            norm 95
          impact 
            freq 38
            norm 107
          impact 
            freq 59
            norm 109
          impact 
            freq 68
            norm 113
          impact 
            freq 175
            norm 114
        impactsEnd 
  term thomas
    doc 1
      freq 1
      pos 8922
    doc 3
      freq 1
      pos 4620
    doc 4
      freq 1
      pos 5478
    doc 11
      freq 2
      pos 6460
      pos 6621
    doc 12
      freq 1
      pos 6824
  term thomson
    doc 12
      freq 3
      pos 7014
      pos 7073
      pos 7260
    doc 15
      freq 1
      pos 3910
  term thorough
    doc 10
      freq 1
      pos 12173
  term those
    doc 0
      freq 8
      pos 1677
      pos 10827
      pos 10837
      pos 11367
      pos 11377
      pos 14427
      pos 14593
      pos 16866
    doc 1
      freq 4
      pos 462
      pos 1963
      pos 3940
      pos 8424
    doc 2
      freq 2
      pos 1533
      pos 4138
    doc 5
      freq 2
      pos 763
      pos 3645
    doc 6
      freq 1
      pos 2118
    doc 7
      freq 3
      pos 378
      pos 1614
      pos 1636
    doc 8
      freq 1
      pos 1710
    doc 10
      freq 8
      pos 5624
      pos 6596
      pos 7312
      pos 8295
      pos 8544
      pos 8785
      pos 9346
      pos 10349
    doc 11
      freq 4
      pos 1104
      pos 2158
      pos 5438
      pos 7498
    doc 12
      freq 8
      pos 138
      pos 540
      pos 1842
      pos 2098
      pos 2451
      pos 8198
      pos 8991
      pos 9210
    doc 13
      freq 8
      pos 2254
      pos 2786
      pos 2900
      pos 2912
      pos 3476
      pos 4640
      pos 5502
      pos 5623
    doc 14
      freq 2
      pos 2063
      pos 2278
    doc 15
      freq 3
      pos 681
      pos 878
      pos 1953
    doc 16
      freq 1
      pos 892
    doc 18
      freq 2
      pos 296
      pos 1621
    skipList 
      level 0
        skipDoc 10
        skipDocFP 2418972
        impacts 
          impact 
            freq 1
            norm 97
          impact 
            freq 3
            norm 100
          impact 
            freq 4
            norm 113
          impact 
            freq 8
            norm 116
        impactsEnd 
  term though
    doc 6
      freq 2
      pos 598
      pos 2549
    doc 10
      freq 1
      pos 9037
    doc 11
      freq 1
      pos 6063
    doc 12
      freq 2
      pos 3932
      pos 4080
    doc 13
      freq 1
      pos 6050
    doc 15
      freq 1
      pos 2903
    doc 18
      freq 2
      pos 1586
      pos 1879
  term thought
    doc 1
      freq 2
      pos 3072
      pos 3271
  term thousands
    doc 13
      freq 1
      pos 3405
  term thread
    doc 12
      freq 1
      pos 7628
  term threads
    doc 12
      freq 1
      pos 3573
  term threat
    doc 5
      freq 5
      pos 2978
      pos 3163
      pos 3286
      pos 3406
      pos 3561
    doc 13
      freq 1
      pos 6665
  term threats
    doc 0
      freq 2
      pos 16182
      pos 16215
    doc 9
      freq 1
      pos 1048
  term three
    doc 0
      freq 2
      pos 440
      pos 17153
    doc 1
      freq 3
      pos 3482
      pos 3790
      pos 8211
    doc 2
      freq 1
      pos 3935
    doc 5
      freq 2
      pos 769
      pos 1999
    doc 8
      freq 1
      pos 231
    doc 11
      freq 1
      pos 2490
    doc 12
      freq 3
      pos 3283
      pos 3659
      pos 8519
    doc 14
      freq 1
      pos 2937
    skipList 
      level 0
        skipDoc 14
        skipDocFP 2421353
        impacts 
          impact 
            freq 1
            norm 97
          impact 
            freq 2
            norm 104
          impact 
            freq 3
            norm 113
        impactsEnd 
  term threshold
    doc 12
      freq 1
      pos 9342
  term throttl
    doc 0
      freq 11
      pos 12879
      pos 13133
      pos 13235
      pos 13452
      pos 13550
      pos 13642
      pos 13744
      pos 13817
      pos 13889
      pos 14029
      pos 14158
  term throttled
    doc 0
      freq 11
      pos 12904
      pos 13158
      pos 13260
      pos 13477
      pos 13575
      pos 13667
      pos 13769
      pos 13842
      pos 13914
      pos 14054
      pos 14183
  term through
    doc 0
      freq 10
      pos 243
      pos 756
      pos 852
      pos 1362
      pos 9965
      pos 10843
      pos 11383
      pos 16342
      pos 16371
      pos 16694
    doc 1
      freq 11
      pos 539
      pos 877
      pos 922
      pos 1296
      pos 1358
      pos 3168
      pos 3171
      pos 5962
      pos 7518
      pos 8361
      pos 8392
    doc 2
      freq 2
      pos 3934
      pos 6169
    doc 3
      freq 3
      pos 1211
      pos 2969
      pos 4279
    doc 4
      freq 2
      pos 994
      pos 4977
    doc 6
      freq 1
      pos 2458
    doc 7
      freq 3
      pos 309
      pos 691
      pos 1987
    doc 8
      freq 16
      pos 504
      pos 516
      pos 536
      pos 556
      pos 835
      pos 846
      pos 866
      pos 887
      pos 1172
      pos 1192
      pos 1212
      pos 1353
      pos 1373
      pos 1393
      pos 1532
      pos 1542
    doc 9
      freq 1
      pos 1298
    doc 10
      freq 6
      pos 822
      pos 4545
      pos 7630
      pos 9046
      pos 10508
      pos 11272
    doc 11
      freq 1
      pos 4201
    doc 12
      freq 6
      pos 3983
      pos 4000
      pos 5821
      pos 7615
      pos 9137
      pos 9229
    doc 13
      freq 2
      pos 2129
      pos 2487
    doc 17
      freq 1
      pos 205
    doc 18
      freq 1
      pos 251
    skipList 
      level 0
        skipDoc 8
        skipDocFP 2422534
        impacts 
          impact 
            freq 16
            norm 97
        impactsEnd 
  term throughout
    doc 5
      freq 2
      pos 2438
      pos 3023
    doc 8
      freq 1
      pos 380
    doc 10
      freq 1
      pos 12846
  term throughput
    doc 12
      freq 1
      pos 2742
  term thu
    doc 10
      freq 6
      pos 6354
      pos 6487
      pos 6639
      pos 7138
      pos 7237
      pos 7351
    doc 16
      freq 4
      pos 1966
      pos 1981
      pos 2334
      pos 2349
  term thus
    doc 0
      freq 2
      pos 5866
      pos 7881
    doc 1
      freq 7
      pos 855
      pos 1269
      pos 1301
      pos 1495
      pos 2815
      pos 3453
      pos 4775
    doc 3
      freq 1
      pos 3382
    doc 4
      freq 1
      pos 715
    doc 5
      freq 2
      pos 431
      pos 1180
    doc 6
      freq 1
      pos 507
    doc 7
      freq 1
      pos 1280
    doc 10
      freq 7
      pos 2036
      pos 5017
      pos 5686
      pos 7108
      pos 9030
      pos 9164
      pos 9516
    doc 13
      freq 19
      pos 865
      pos 897
      pos 2217
      pos 2304
      pos 2448
      pos 2492
      pos 2704
      pos 3462
      pos 3551
      pos 3903
      pos 4579
      pos 4646
      pos 4950
      pos 5203
      pos 5299
      pos 5555
      pos 6045
      pos 6598
      pos 6684
    doc 14
      freq 2
      pos 1103
      pos 1749
    doc 15
      freq 6
      pos 435
      pos 1710
      pos 2291
      pos 3170
      pos 3397
      pos 3666
    doc 17
      freq 1
      pos 349
    skipList 
      level 0
        skipDoc 10
        skipDocFP 2424458
        impacts 
          impact 
            freq 1
            norm 100
          impact 
            freq 2
            norm 104
          impact 
            freq 7
            norm 113
        impactsEnd 
  term tie
    doc 10
      freq 1
      pos 8715
    doc 17
      freq 1
      pos 1790
  term tied
    doc 17
      freq 1
      pos 1694
  term ties
    doc 0
      freq 1
      pos 1478
  term tightly
    doc 2
      freq 1
      pos 1992
  term tim
    doc 15
      freq 1
      pos 4016
  term time
    doc 0
      freq 21
      pos 2159
      pos 2184
      pos 2202
      pos 5573
      pos 6810
      pos 6993
      pos 7110
      pos 9261
      pos 9278
      pos 12915
      pos 13049
      pos 13169
      pos 13271
      pos 13488
      pos 13586
      pos 13678
      pos 13780
      pos 13853
      pos 13937
      pos 14065
      pos 14194
    doc 1
      freq 8
      pos 150
      pos 566
      pos 657
      pos 6959
      pos 6995
      pos 7630
      pos 8315
      pos 8322
    doc 2
      freq 14
      pos 186
      pos 805
      pos 1085
      pos 3640
      pos 3716
      pos 3800
      pos 3958
      pos 4164
      pos 4291
      pos 4419
      pos 5155
      pos 5268
      pos 5584
      pos 6344
    doc 4
      freq 9
      pos 198
      pos 777
      pos 3000
      pos 3088
      pos 3146
      pos 3174
      pos 3213
      pos 4711
      pos 5683
    doc 5
      freq 23
      pos 129
      pos 158
      pos 285
      pos 490
      pos 612
      pos 1979
      pos 2060
      pos 2129
      pos 2138
      pos 2146
      pos 2195
      pos 2240
      pos 2296
      pos 2339
      pos 2372
      pos 2411
      pos 2456
      pos 2590
      pos 3759
      pos 4082
      pos 4230
      pos 4291
      pos 4368
    doc 6
      freq 25
      pos 220
      pos 334
      pos 409
      pos 463
      pos 687
      pos 1046
      pos 1080
      pos 1083
      pos 1268
      pos 1408
      pos 1412
      pos 1457
      pos 1489
      pos 1539
      pos 1766
      pos 1837
      pos 1856
      pos 1959
      pos 1983
      pos 2058
      pos 2224
      pos 2472
      pos 2667
      pos 3078
      pos 3110
    doc 7
      freq 1
      pos 286
    doc 10
      freq 5
      pos 3192
      pos 3202
      pos 3971
      pos 8517
      pos 9678
    doc 11
      freq 4
      pos 4443
      pos 6030
      pos 6046
      pos 6129
    doc 12
      freq 11
      pos 1804
      pos 1874
      pos 2054
      pos 2759
      pos 3639
      pos 3805
      pos 4510
      pos 4776
      pos 5771
      pos 6631
      pos 6937
    doc 13
      freq 18
      pos 804
      pos 1498
      pos 2137
      pos 2223
      pos 2484
      pos 2841
      pos 2861
      pos 3002
      pos 3244
      pos 3425
      pos 3437
      pos 3480
      pos 4138
      pos 4527
      pos 4716
      pos 4862
      pos 4959
      pos 6512
    doc 14
      freq 1
      pos 359
    doc 15
      freq 2
      pos 1933
      pos 3677
    doc 16
      freq 4
      pos 566
      pos 613
      pos 656
      pos 705
    doc 18
      freq 1
      pos 510
    skipList 
      level 0
        skipDoc 10
        skipDocFP 2426071
        impacts 
          impact 
            freq 1
            norm 100
          impact 
            freq 25
            norm 101
        impactsEnd 
  term timed
    doc 5
      freq 4
      pos 18
      pos 88
      pos 4194
      pos 4219
  term timelines
    doc 7
      freq 1
      pos 167
  term timeliness
    doc 13
      freq 1
      pos 2846
  term timely
    doc 2
      freq 1
      pos 3863
    doc 13
      freq 1
      pos 4192
  term timeout
    doc 4
      freq 2
      pos 3186
      pos 5689
  term timer
    doc 0
      freq 2
      pos 2219
      pos 2634
    doc 4
      freq 2
      pos 1961
      pos 5584
  term times
    doc 0
      freq 19
      pos 678
      pos 7455
      pos 7482
      pos 7524
      pos 7555
      pos 7582
      pos 7626
      pos 7693
      pos 7910
      pos 7978
      pos 8019
      pos 8058
      pos 8099
      pos 8153
      pos 8190
      pos 8224
      pos 12811
      pos 12866
      pos 12948
    doc 6
      freq 1
      pos 2009
    doc 13
      freq 2
      pos 3026
      pos 3048
    doc 15
      freq 1
      pos 3138
  term timestamp
    doc 0
      freq 5
      pos 1015
      pos 5504
      pos 6134
      pos 8907
      pos 9321
    doc 5
      freq 7
      pos 1973
      pos 2150
      pos 2306
      pos 2382
      pos 2395
      pos 2404
      pos 2524
    doc 11
      freq 1
      pos 4877
  term timetr
    doc 3
      freq 2
      pos 4961
      pos 4975
  term timetra.com
    doc 3
      freq 2
      pos 4972
      pos 4986
  term timezon
    doc 11
      freq 1
      pos 330
  term tingl
    doc 3
      freq 1
      pos 4960
  term tiny
    doc 14
      freq 1
      pos 1313
  term tislabs.com
    doc 18
      freq 1
      pos 2173
  term title
    doc 0
      freq 1
      pos 1425
    doc 13
      freq 2
      pos 1308
      pos 3521
  term titles
    doc 0
      freq 1
      pos 2415
  term tjc
    doc 15
      freq 1
      pos 4034
  term tke
    doc 10
      freq 1
      pos 6871
  term tkk
    doc 13
      freq 1
      pos 7052
  term tl
    doc 11
      freq 1
      pos 9956
  term tla
    doc 3
      freq 1
      pos 4989
  term tls
    doc 3
      freq 1
      pos 5242
    doc 10
      freq 18
      pos 533
      pos 1378
      pos 1841
      pos 2636
      pos 4367
      pos 6329
      pos 6614
      pos 6981
      pos 7118
      pos 7331
      pos 10036
      pos 10063
      pos 10120
      pos 10233
      pos 10293
      pos 10648
      pos 10774
      pos 13279
    doc 11
      freq 2
      pos 3657
      pos 7765
  term tlv
    doc 0
      freq 18
      pos 915
      pos 12012
      pos 12082
      pos 12139
      pos 12145
      pos 12152
      pos 12230
      pos 12249
      pos 12272
      pos 12553
      pos 12561
      pos 12695
      pos 12703
      pos 12741
      pos 14145
      pos 14152
      pos 14306
      pos 14314
    doc 1
      freq 90
      pos 276
      pos 281
      pos 315
      pos 368
      pos 2094
      pos 2097
      pos 2107
      pos 2123
      pos 2193
      pos 2211
      pos 2246
      pos 2262
      pos 2288
      pos 2297
      pos 2303
      pos 2309
      pos 2501
      pos 2593
      pos 2766
      pos 2770
      pos 2790
      pos 3016
      pos 3020
      pos 3044
      pos 3947
      pos 3949
      pos 4039
      pos 4043
      pos 4068
      pos 4073
      pos 4115
      pos 4215
      pos 4269
      pos 4308
      pos 4392
      pos 4564
      pos 4577
      pos 4590
      pos 4595
      pos 5034
      pos 5045
      pos 5062
      pos 5212
      pos 5277
      pos 5280
      pos 5283
      pos 5288
      pos 5305
      pos 5344
      pos 5392
      pos 5418
      pos 5432
      pos 5439
      pos 5457
      pos 5556
      pos 5563
      pos 5627
      pos 5640
      pos 5663
      pos 5758
      pos 5789
      pos 5801
      pos 5821
      pos 5844
      pos 5848
      pos 5875
      pos 5882
      pos 5898
      pos 5932
      pos 5944
      pos 5970
      pos 6067
      pos 6080
      pos 6138
      pos 6218
      pos 7112
      pos 7186
      pos 7232
      pos 7238
      pos 7245
      pos 7289
      pos 7316
      pos 7346
      pos 7745
      pos 7753
      pos 7762
      pos 7777
      pos 7783
      pos 7788
      pos 7792
    doc 3
      freq 6
      pos 216
      pos 1555
      pos 1934
      pos 1981
      pos 1997
      pos 2018
    doc 5
      freq 1
      pos 1776
    doc 8
      freq 10
      pos 134
      pos 809
      pos 823
      pos 832
      pos 843
      pos 863
      pos 883
      pos 1001
      pos 1108
      pos 1112
  term tlvs
    doc 0
      freq 3
      pos 923
      pos 3542
      pos 12001
    doc 1
      freq 15
      pos 755
      pos 783
      pos 2104
      pos 2147
      pos 2165
      pos 2241
      pos 2282
      pos 2625
      pos 2842
      pos 3863
      pos 5352
      pos 5524
      pos 5659
      pos 7179
      pos 7314
  term tmux
    doc 7
      freq 2
      pos 1036
      pos 2581
  term tngv
    doc 11
      freq 1
      pos 10272
  term tnvmfalafwhzhg6hworiohz2um5kzcv4
    doc 10
      freq 1
      pos 12524
  term to
    doc 0
      freq 235
      pos 23
      pos 53
      pos 120
      pos 131
      pos 215
      pos 276
      pos 312
      pos 329
      pos 431
      pos 445
      pos 468
      pos 506
      pos 553
      pos 563
      pos 593
      pos 613
      pos 628
      pos 631
      pos 646
      pos 697
      pos 737
      pos 977
      pos 1144
      pos 1173
      pos 1177
      pos 1187
      pos 1190
      pos 1377
      pos 1476
      pos 1557
      pos 1560
      pos 1957
      pos 2033
      pos 2068
      pos 2110
      pos 2135
      pos 2154
      pos 2227
      pos 2253
      pos 2404
      pos 2410
      pos 2445
      pos 2489
      pos 2626
      pos 2677
      pos 2742
      pos 2784
      pos 2818
      pos 2875
      pos 2989
      pos 3005
      pos 3104
      pos 3272
      pos 3276
      pos 3510
      pos 3537
      pos 3555
      pos 3616
      pos 3853
      pos 3936
      pos 3967
      pos 3993
      pos 4029
      pos 4039
      pos 4115
      pos 4132
      pos 4353
      pos 4932
      pos 4985
      pos 5068
      pos 5221
      pos 5253
      pos 5269
      pos 5318
      pos 5356
      pos 5370
      pos 5377
      pos 5524
      pos 5607
      pos 5664
      pos 5682
      pos 6001
      pos 6053
      pos 6109
      pos 6119
      pos 6123
      pos 6202
      pos 6224
      pos 6525
      pos 6539
      pos 6556
      pos 6566
      pos 6592
      pos 6622
      pos 6630
      pos 6662
      pos 6814
      pos 6878
      pos 6891
      pos 7058
      pos 7529
      pos 7740
      pos 7861
      pos 7878
      pos 7887
      pos 7994
      pos 8203
      pos 8241
      pos 8464
      pos 8800
      pos 8804
      pos 8840
      pos 8860
      pos 8863
      pos 9024
      pos 9040
      pos 9193
      pos 9521
      pos 9694
      pos 9702
      pos 9987
      pos 10013
      pos 10254
      pos 10257
      pos 10307
      pos 10319
      pos 10341
      pos 10345
      pos 10445
      pos 10450
      pos 10551
      pos 10560
      pos 10644
      pos 10736
      pos 10902
      pos 10936
      pos 10959
      pos 10973
      pos 11217
      pos 11325
      pos 11607
      pos 11616
      pos 12351
      pos 12396
      pos 12522
      pos 12566
      pos 12683
      pos 12698
      pos 12713
      pos 12845
      pos 13027
      pos 13103
      pos 13363
      pos 13379
      pos 13873
      pos 14297
      pos 14309
      pos 14345
      pos 15467
      pos 15535
      pos 15581
      pos 15614
      pos 15686
      pos 15714
      pos 15756
      pos 15786
      pos 15867
      pos 15872
      pos 15882
      pos 15891
      pos 15901
      pos 16000
      pos 16008
      pos 16020
      pos 16023
      pos 16030
      pos 16033
      pos 16044
      pos 16063
      pos 16071
      pos 16088
      pos 16168
      pos 16208
      pos 16254
      pos 16282
      pos 16308
      pos 16335
      pos 16366
      pos 16387
      pos 16391
      pos 16424
      pos 16435
      pos 16452
      pos 16455
      pos 16497
      pos 16506
      pos 16552
      pos 16586
      pos 16623
      pos 16668
      pos 16677
      pos 16683
      pos 16699
      pos 16713
      pos 16750
      pos 16776
      pos 16784
      pos 16804
      pos 16813
      pos 16817
      pos 16828
      pos 16836
      pos 16858
      pos 16861
      pos 16865
      pos 16873
      pos 16890
      pos 16934
      pos 16950
      pos 17159
      pos 17165
      pos 17236
      pos 17305
      pos 17356
      pos 17358
      pos 17373
      pos 17397
      pos 17408
      pos 17427
      pos 17436
      pos 17447
      pos 17488
      pos 17490
      pos 17511
      pos 17519
    doc 1
      freq 237
      pos 70
      pos 143
      pos 146
      pos 178
      pos 230
      pos 446
      pos 477
      pos 512
      pos 523
      pos 531
      pos 537
      pos 555
      pos 602
      pos 647
      pos 679
      pos 766
      pos 770
      pos 786
      pos 792
      pos 867
      pos 918
      pos 971
      pos 976
      pos 980
      pos 1007
      pos 1179
      pos 1195
      pos 1204
      pos 1224
      pos 1236
      pos 1239
      pos 1254
      pos 1306
      pos 1326
      pos 1333
      pos 1341
      pos 1353
      pos 1420
      pos 1437
      pos 1448
      pos 1480
      pos 1492
      pos 1576
      pos 1587
      pos 1590
      pos 1619
      pos 1622
      pos 1645
      pos 1648
      pos 1705
      pos 1874
      pos 1905
      pos 1913
      pos 1917
      pos 1946
      pos 1961
      pos 1977
      pos 1999
      pos 2110
      pos 2127
      pos 2138
      pos 2148
      pos 2170
      pos 2194
      pos 2283
      pos 2527
      pos 2541
      pos 2642
      pos 2654
      pos 2666
      pos 2684
      pos 2721
      pos 2773
      pos 2803
      pos 2824
      pos 2913
      pos 2956
      pos 2967
      pos 2994
      pos 3081
      pos 3096
      pos 3112
      pos 3114
      pos 3121
      pos 3207
      pos 3238
      pos 3243
      pos 3297
      pos 3304
      pos 3388
      pos 3405
      pos 3720
      pos 3780
      pos 3806
      pos 3939
      pos 3972
      pos 3993
      pos 4139
      pos 4158
      pos 4163
      pos 4174
      pos 4186
      pos 4206
      pos 4281
      pos 4294
      pos 4325
      pos 4380
      pos 4429
      pos 4457
      pos 4530
      pos 4542
      pos 4604
      pos 4657
      pos 4687
      pos 4699
      pos 4708
      pos 4740
      pos 4755
      pos 4761
      pos 4796
      pos 4820
      pos 4894
      pos 4952
      pos 5035
      pos 5038
      pos 5139
      pos 5152
      pos 5215
      pos 5310
      pos 5314
      pos 5326
      pos 5339
      pos 5380
      pos 5399
      pos 5468
      pos 5510
      pos 5550
      pos 5590
      pos 5600
      pos 5619
      pos 5806
      pos 5911
      pos 5983
      pos 6004
      pos 6091
      pos 6183
      pos 6229
      pos 6239
      pos 6249
      pos 6266
      pos 6307
      pos 6493
      pos 6641
      pos 6703
      pos 6705
      pos 6724
      pos 6736
      pos 6739
      pos 6857
      pos 6946
      pos 7011
      pos 7019
      pos 7037
      pos 7044
      pos 7059
      pos 7067
      pos 7123
      pos 7166
      pos 7226
      pos 7271
      pos 7280
      pos 7292
      pos 7306
      pos 7383
      pos 7416
      pos 7451
      pos 7478
      pos 7529
      pos 7558
      pos 7575
      pos 7605
      pos 7614
      pos 7625
      pos 7647
      pos 7679
      pos 7693
      pos 7704
      pos 7723
      pos 7952
      pos 7957
      pos 7970
      pos 7994
      pos 8037
      pos 8052
      pos 8093
      pos 8102
      pos 8111
      pos 8116
      pos 8125
      pos 8147
      pos 8151
      pos 8165
      pos 8181
      pos 8187
      pos 8222
      pos 8261
      pos 8296
      pos 8411
      pos 8428
      pos 8435
      pos 8448
      pos 8469
      pos 8492
      pos 8567
      pos 8736
      pos 8782
      pos 8784
      pos 8807
      pos 8839
      pos 8875
      pos 8903
      pos 8961
      pos 9157
      pos 9617
      pos 9686
      pos 9737
      pos 9739
      pos 9754
      pos 9778
      pos 9789
      pos 9808
      pos 9817
      pos 9828
      pos 9869
      pos 9871
      pos 9892
      pos 9900
    doc 2
      freq 183
      pos 98
      pos 124
      pos 234
      pos 316
      pos 337
      pos 463
      pos 477
      pos 484
      pos 506
      pos 542
      pos 550
      pos 557
      pos 561
      pos 570
      pos 590
      pos 607
      pos 612
      pos 617
      pos 643
      pos 659
      pos 665
      pos 674
      pos 683
      pos 694
      pos 714
      pos 726
      pos 731
      pos 759
      pos 790
      pos 808
      pos 812
      pos 830
      pos 855
      pos 868
      pos 879
      pos 882
      pos 898
      pos 911
      pos 925
      pos 945
      pos 983
      pos 996
      pos 1022
      pos 1040
      pos 1061
      pos 1141
      pos 1153
      pos 1164
      pos 1185
      pos 1188
      pos 1203
      pos 1218
      pos 1273
      pos 1310
      pos 1336
      pos 1362
      pos 1416
      pos 1491
      pos 1548
      pos 1590
      pos 1680
      pos 1694
      pos 1712
      pos 1764
      pos 1927
      pos 1965
      pos 1974
      pos 1983
      pos 1999
      pos 2005
      pos 2008
      pos 2051
      pos 2099
      pos 2119
      pos 2142
      pos 2162
      pos 2176
      pos 2204
      pos 2261
      pos 2276
      pos 2356
      pos 2370
      pos 2434
      pos 2659
      pos 2756
      pos 2779
      pos 2837
      pos 3457
      pos 3479
      pos 3722
      pos 3804
      pos 3811
      pos 3823
      pos 3844
      pos 3854
      pos 3858
      pos 4058
      pos 4159
      pos 4180
      pos 4292
      pos 4390
      pos 4415
      pos 4561
      pos 4573
      pos 4578
      pos 4642
      pos 4683
      pos 4692
      pos 4713
      pos 4759
      pos 4772
      pos 4803
      pos 4810
      pos 4850
      pos 4858
      pos 4898
      pos 4976
      pos 5084
      pos 5095
      pos 5103
      pos 5133
      pos 5170
      pos 5240
      pos 5248
      pos 5279
      pos 5312
      pos 5347
      pos 5350
      pos 5363
      pos 5376
      pos 5463
      pos 5521
      pos 5551
      pos 5560
      pos 5575
      pos 5587
      pos 5615
      pos 5636
      pos 5640
      pos 5688
      pos 5742
      pos 5754
      pos 5787
      pos 5834
      pos 5839
      pos 5847
      pos 5867
      pos 5916
      pos 5920
      pos 5930
      pos 5939
      pos 5968
      pos 5981
      pos 6017
      pos 6022
      pos 6070
      pos 6080
      pos 6094
      pos 6100
      pos 6106
      pos 6135
      pos 6141
      pos 6205
      pos 6244
      pos 6249
      pos 6255
      pos 6267
      pos 6281
      pos 6323
      pos 6414
      pos 6483
      pos 6534
      pos 6536
      pos 6551
      pos 6575
      pos 6586
      pos 6605
      pos 6614
      pos 6625
      pos 6666
      pos 6668
      pos 6689
      pos 6697
    doc 3
      freq 140
      pos 64
      pos 106
      pos 122
      pos 152
      pos 156
      pos 194
      pos 316
      pos 355
      pos 418
      pos 447
      pos 483
      pos 502
      pos 515
      pos 565
      pos 688
      pos 694
      pos 704
      pos 833
      pos 900
      pos 951
      pos 985
      pos 1017
      pos 1049
      pos 1112
      pos 1153
      pos 1179
      pos 1205
      pos 1216
      pos 1254
      pos 1274
      pos 1278
      pos 1300
      pos 1323
      pos 1433
      pos 1465
      pos 1590
      pos 1643
      pos 1690
      pos 1705
      pos 1738
      pos 1824
      pos 1829
      pos 1834
      pos 1853
      pos 1891
      pos 1912
      pos 1921
      pos 1952
      pos 1973
      pos 2070
      pos 2105
      pos 2135
      pos 2164
      pos 2191
      pos 2201
      pos 2229
      pos 2309
      pos 2319
      pos 2382
      pos 2395
      pos 2405
      pos 2417
      pos 2463
      pos 2534
      pos 2672
      pos 2748
      pos 2958
      pos 2961
      pos 3053
      pos 3168
      pos 3289
      pos 3323
      pos 3342
      pos 3372
      pos 3429
      pos 3460
      pos 3543
      pos 3548
      pos 3558
      pos 3685
      pos 3687
      pos 3707
      pos 3729
      pos 3761
      pos 3805
      pos 3865
      pos 3935
      pos 3966
      pos 3980
      pos 3996
      pos 4074
      pos 4149
      pos 4191
      pos 4225
      pos 4245
      pos 4321
      pos 4344
      pos 4501
      pos 4524
      pos 4582
      pos 5030
      pos 5144
      pos 5167
      pos 5178
      pos 5236
      pos 5253
      pos 5299
      pos 5344
      pos 5347
      pos 5374
      pos 5421
      pos 5450
      pos 5457
      pos 5472
      pos 5491
      pos 5501
      pos 5521
      pos 5527
      pos 5531
      pos 5540
      pos 5551
      pos 5555
      pos 5563
      pos 5602
      pos 5630
      pos 5827
      pos 5966
      pos 6035
      pos 6086
      pos 6088
      pos 6103
      pos 6127
      pos 6138
      pos 6157
      pos 6166
      pos 6177
      pos 6218
      pos 6220
      pos 6241
      pos 6249
    doc 4
      freq 165
      pos 66
      pos 345
      pos 378
      pos 409
      pos 463
      pos 482
      pos 490
      pos 573
      pos 656
      pos 669
      pos 723
      pos 732
      pos 1030
      pos 1045
      pos 1070
      pos 1114
      pos 1118
      pos 1143
      pos 1147
      pos 1172
      pos 1188
      pos 1197
      pos 1204
      pos 1237
      pos 1341
      pos 1393
      pos 1478
      pos 1484
      pos 1511
      pos 1518
      pos 1529
      pos 1579
      pos 1585
      pos 1610
      pos 1616
      pos 1626
      pos 1665
      pos 1674
      pos 1685
      pos 1690
      pos 1725
      pos 1743
      pos 1778
      pos 1814
      pos 1824
      pos 1864
      pos 1903
      pos 1923
      pos 1927
      pos 2005
      pos 2171
      pos 2201
      pos 2216
      pos 2248
      pos 2255
      pos 2277
      pos 2285
      pos 2304
      pos 2345
      pos 2359
      pos 2367
      pos 2386
      pos 2431
      pos 2448
      pos 2453
      pos 2463
      pos 2472
      pos 2509
      pos 2519
      pos 2523
      pos 2530
      pos 2572
      pos 2593
      pos 2603
      pos 2617
      pos 2628
      pos 2636
      pos 2642
      pos 2654
      pos 2665
      pos 2701
      pos 2835
      pos 2869
      pos 2913
      pos 2919
      pos 2921
      pos 2935
      pos 2983
      pos 3103
      pos 3135
      pos 3152
      pos 3182
      pos 3219
      pos 3417
      pos 3606
      pos 3612
      pos 3639
      pos 3645
      pos 3708
      pos 3875
      pos 3902
      pos 3908
      pos 3930
      pos 3971
      pos 3987
      pos 4104
      pos 4136
      pos 4139
      pos 4143
      pos 4174
      pos 4184
      pos 4187
      pos 4194
      pos 4196
      pos 4198
      pos 4327
      pos 4357
      pos 4366
      pos 4411
      pos 4418
      pos 4461
      pos 4510
      pos 4551
      pos 4559
      pos 4572
      pos 4580
      pos 4630
      pos 4689
      pos 4784
      pos 5084
      pos 5117
      pos 5276
      pos 5555
      pos 5569
      pos 5576
      pos 5579
      pos 5659
      pos 5672
      pos 5705
      pos 5708
      pos 5743
      pos 5759
      pos 5792
      pos 5851
      pos 5877
      pos 5923
      pos 5945
      pos 5954
      pos 5974
      pos 6003
      pos 6016
      pos 6121
      pos 6190
      pos 6241
      pos 6243
      pos 6258
      pos 6282
      pos 6293
      pos 6312
      pos 6321
      pos 6332
      pos 6373
      pos 6375
      pos 6396
      pos 6404
    doc 5
      freq 121
      pos 50
      pos 114
      pos 174
      pos 370
      pos 456
      pos 506
      pos 531
      pos 538
      pos 550
      pos 617
      pos 634
      pos 644
      pos 646
      pos 663
      pos 683
      pos 705
      pos 737
      pos 742
      pos 798
      pos 857
      pos 866
      pos 887
      pos 926
      pos 949
      pos 971
      pos 988
      pos 1020
      pos 1032
      pos 1067
      pos 1081
      pos 1090
      pos 1124
      pos 1168
      pos 1186
      pos 1224
      pos 1240
      pos 1255
      pos 1350
      pos 1423
      pos 1462
      pos 1494
      pos 1525
      pos 1555
      pos 1668
      pos 1673
      pos 1697
      pos 2148
      pos 2171
      pos 2184
      pos 2222
      pos 2316
      pos 2346
      pos 2464
      pos 2470
      pos 2534
      pos 2574
      pos 2578
      pos 2771
      pos 2829
      pos 2842
      pos 2851
      pos 2865
      pos 2877
      pos 2917
      pos 2956
      pos 2969
      pos 2998
      pos 3090
      pos 3115
      pos 3149
      pos 3175
      pos 3201
      pos 3208
      pos 3216
      pos 3229
      pos 3291
      pos 3301
      pos 3317
      pos 3329
      pos 3377
      pos 3381
      pos 3387
      pos 3412
      pos 3432
      pos 3487
      pos 3527
      pos 3549
      pos 3567
      pos 3587
      pos 3593
      pos 3610
      pos 3617
      pos 3622
      pos 3685
      pos 3743
      pos 3747
      pos 3780
      pos 3809
      pos 3827
      pos 3858
      pos 3887
      pos 3996
      pos 4025
      pos 4038
      pos 4069
      pos 4088
      pos 4131
      pos 4451
      pos 4520
      pos 4571
      pos 4573
      pos 4588
      pos 4612
      pos 4623
      pos 4642
      pos 4651
      pos 4662
      pos 4703
      pos 4705
      pos 4726
      pos 4734
    doc 6
      freq 87
      pos 83
      pos 117
      pos 147
      pos 202
      pos 218
      pos 314
      pos 325
      pos 360
      pos 377
      pos 383
      pos 396
      pos 402
      pos 454
      pos 459
      pos 472
      pos 480
      pos 525
      pos 535
      pos 577
      pos 580
      pos 590
      pos 609
      pos 623
      pos 692
      pos 727
      pos 753
      pos 773
      pos 792
      pos 801
      pos 858
      pos 865
      pos 929
      pos 958
      pos 971
      pos 990
      pos 1012
      pos 1031
      pos 1090
      pos 1100
      pos 1227
      pos 1345
      pos 1356
      pos 1372
      pos 1390
      pos 1416
      pos 1420
      pos 1484
      pos 1510
      pos 1533
      pos 1544
      pos 1634
      pos 1639
      pos 1642
      pos 1652
      pos 1689
      pos 1702
      pos 1854
      pos 2088
      pos 2143
      pos 2205
      pos 2225
      pos 2318
      pos 2400
      pos 2406
      pos 2435
      pos 2494
      pos 2521
      pos 2602
      pos 2624
      pos 2790
      pos 2838
      pos 2862
      pos 2908
      pos 3246
      pos 3320
      pos 3371
      pos 3373
      pos 3388
      pos 3412
      pos 3423
      pos 3442
      pos 3451
      pos 3462
      pos 3503
      pos 3505
      pos 3526
      pos 3534
    doc 7
      freq 73
      pos 78
      pos 182
      pos 237
      pos 249
      pos 275
      pos 279
      pos 319
      pos 371
      pos 379
      pos 397
      pos 423
      pos 429
      pos 516
      pos 530
      pos 555
      pos 561
      pos 600
      pos 611
      pos 621
      pos 646
      pos 700
      pos 710
      pos 742
      pos 889
      pos 933
      pos 977
      pos 1126
      pos 1221
      pos 1233
      pos 1244
      pos 1251
      pos 1253
      pos 1310
      pos 1347
      pos 1369
      pos 1472
      pos 1527
      pos 1592
      pos 1686
      pos 1716
      pos 1723
      pos 1745
      pos 1761
      pos 1797
      pos 1996
      pos 2034
      pos 2047
      pos 2086
      pos 2298
      pos 2315
      pos 2334
      pos 2353
      pos 2397
      pos 2429
      pos 2512
      pos 2514
      pos 2522
      pos 2699
      pos 2785
      pos 2956
      pos 3025
      pos 3076
      pos 3078
      pos 3093
      pos 3117
      pos 3128
      pos 3147
      pos 3156
      pos 3167
      pos 3208
      pos 3210
      pos 3231
      pos 3239
    doc 8
      freq 59
      pos 25
      pos 90
      pos 236
      pos 243
      pos 247
      pos 256
      pos 261
      pos 327
      pos 356
      pos 395
      pos 519
      pos 541
      pos 566
      pos 676
      pos 685
      pos 699
      pos 708
      pos 813
      pos 849
      pos 871
      pos 897
      pos 923
      pos 946
      pos 955
      pos 963
      pos 967
      pos 1030
      pos 1142
      pos 1175
      pos 1197
      pos 1222
      pos 1248
      pos 1323
      pos 1356
      pos 1378
      pos 1403
      pos 1429
      pos 1513
      pos 1545
      pos 1570
      pos 1642
      pos 1660
      pos 1690
      pos 1771
      pos 2112
      pos 2173
      pos 2242
      pos 2293
      pos 2295
      pos 2310
      pos 2334
      pos 2345
      pos 2364
      pos 2373
      pos 2384
      pos 2425
      pos 2427
      pos 2448
      pos 2456
    doc 9
      freq 62
      pos 52
      pos 165
      pos 184
      pos 193
      pos 265
      pos 273
      pos 281
      pos 308
      pos 318
      pos 330
      pos 364
      pos 415
      pos 429
      pos 453
      pos 462
      pos 477
      pos 488
      pos 544
      pos 637
      pos 643
      pos 660
      pos 721
      pos 799
      pos 868
      pos 926
      pos 948
      pos 1000
      pos 1026
      pos 1042
      pos 1046
      pos 1060
      pos 1100
      pos 1125
      pos 1137
      pos 1327
      pos 1333
      pos 1362
      pos 1408
      pos 1494
      pos 1508
      pos 1524
      pos 1540
      pos 1553
      pos 1565
      pos 1590
      pos 1625
      pos 1635
      pos 1674
      pos 1818
      pos 1887
      pos 1938
      pos 1940
      pos 1955
      pos 1979
      pos 1990
      pos 2009
      pos 2018
      pos 2029
      pos 2070
      pos 2072
      pos 2093
      pos 2101
    doc 10
      freq 307
      pos 55
      pos 160
      pos 288
      pos 408
      pos 447
      pos 490
      pos 557
      pos 591
      pos 594
      pos 597
      pos 694
      pos 796
      pos 817
      pos 862
      pos 899
      pos 908
      pos 916
      pos 950
      pos 964
      pos 1001
      pos 1003
      pos 1061
      pos 1067
      pos 1080
      pos 1142
      pos 1157
      pos 1186
      pos 1222
      pos 1269
      pos 1306
      pos 1308
      pos 1349
      pos 1361
      pos 1371
      pos 1426
      pos 1434
      pos 1453
      pos 1457
      pos 1504
      pos 1579
      pos 1614
      pos 1619
      pos 1622
      pos 1625
      pos 1635
      pos 1676
      pos 1814
      pos 1842
      pos 1868
      pos 1902
      pos 1980
      pos 2010
      pos 2062
      pos 2180
      pos 2192
      pos 2199
      pos 2250
      pos 2282
      pos 2295
      pos 2330
      pos 2370
      pos 2403
      pos 2425
      pos 2537
      pos 2548
      pos 2686
      pos 2777
      pos 2815
      pos 2878
      pos 2929
      pos 2947
      pos 3064
      pos 3182
      pos 3234
      pos 3238
      pos 3247
      pos 3313
      pos 3326
      pos 3420
      pos 3430
      pos 3449
      pos 3487
      pos 3505
      pos 3530
      pos 3538
      pos 3611
      pos 3648
      pos 3676
      pos 3680
      pos 3686
      pos 3742
      pos 3823
      pos 3843
      pos 3899
      pos 3961
      pos 4005
      pos 4013
      pos 4087
      pos 4163
      pos 4229
      pos 4267
      pos 4304
      pos 4320
      pos 4329
      pos 4338
      pos 4432
      pos 4441
      pos 4456
      pos 4469
      pos 4524
      pos 4527
      pos 4555
      pos 4635
      pos 4641
      pos 4662
      pos 4685
      pos 4700
      pos 4710
      pos 4871
      pos 4926
      pos 4952
      pos 4959
      pos 5009
      pos 5024
      pos 5029
      pos 5113
      pos 5366
      pos 5580
      pos 5652
      pos 5699
      pos 5776
      pos 5900
      pos 5966
      pos 5990
      pos 6198
      pos 6293
      pos 6297
      pos 6310
      pos 6334
      pos 6428
      pos 6433
      pos 6619
      pos 6735
      pos 6826
      pos 6921
      pos 6926
      pos 6949
      pos 6994
      pos 7032
      pos 7037
      pos 7053
      pos 7080
      pos 7131
      pos 7344
      pos 7456
      pos 7488
      pos 7493
      pos 7541
      pos 7562
      pos 7572
      pos 7626
      pos 7656
      pos 7669
      pos 7732
      pos 7823
      pos 7879
      pos 8050
      pos 8113
      pos 8198
      pos 8230
      pos 8249
      pos 8264
      pos 8285
      pos 8343
      pos 8385
      pos 8401
      pos 8579
      pos 8714
      pos 8719
      pos 8733
      pos 8756
      pos 8775
      pos 8789
      pos 8823
      pos 8877
      pos 8880
      pos 8883
      pos 8929
      pos 8932
      pos 8939
      pos 9020
      pos 9088
      pos 9137
      pos 9204
      pos 9216
      pos 9240
      pos 9282
      pos 9299
      pos 9315
      pos 9335
      pos 9343
      pos 9362
      pos 9370
      pos 9441
      pos 9450
      pos 9523
      pos 9690
      pos 9718
      pos 9793
      pos 9813
      pos 9817
      pos 9835
      pos 9915
      pos 9990
      pos 10012
      pos 10037
      pos 10067
      pos 10094
      pos 10112
      pos 10166
      pos 10177
      pos 10199
      pos 10258
      pos 10318
      pos 10323
      pos 10471
      pos 10489
      pos 10492
      pos 10526
      pos 10547
      pos 10568
      pos 10579
      pos 10585
      pos 10594
      pos 10608
      pos 10611
      pos 10633
      pos 10674
      pos 10678
      pos 10690
      pos 10704
      pos 10718
      pos 10733
      pos 10780
      pos 10838
      pos 10868
      pos 11000
      pos 11052
      pos 11100
      pos 11137
      pos 11173
      pos 11278
      pos 11342
      pos 11353
      pos 11392
      pos 11431
      pos 11449
      pos 11512
      pos 11586
      pos 11612
      pos 11707
      pos 11808
      pos 11881
      pos 11902
      pos 11944
      pos 11961
      pos 12026
      pos 12044
      pos 12107
      pos 12144
      pos 12166
      pos 12344
      pos 12361
      pos 12371
      pos 12376
      pos 12430
      pos 12439
      pos 12874
      pos 12904
      pos 12932
      pos 12953
      pos 12960
      pos 12970
      pos 12973
      pos 12995
      pos 13013
      pos 13022
      pos 13034
      pos 13046
      pos 13055
      pos 13125
      pos 13296
      pos 13346
      pos 13479
      pos 13548
      pos 13599
      pos 13601
      pos 13616
      pos 13640
      pos 13651
      pos 13670
      pos 13679
      pos 13690
      pos 13731
      pos 13733
      pos 13754
      pos 13762
    doc 11
      freq 169
      pos 88
      pos 338
      pos 669
      pos 673
      pos 682
      pos 694
      pos 742
      pos 751
      pos 797
      pos 831
      pos 869
      pos 1151
      pos 1456
      pos 1668
      pos 1823
      pos 1913
      pos 1942
      pos 1957
      pos 2045
      pos 2058
      pos 2093
      pos 2141
      pos 2151
      pos 2201
      pos 2341
      pos 2361
      pos 2454
      pos 2463
      pos 2525
      pos 2559
      pos 2679
      pos 2736
      pos 2800
      pos 3246
      pos 3298
      pos 3333
      pos 3515
      pos 3618
      pos 3720
      pos 3814
      pos 4028
      pos 4151
      pos 4209
      pos 4276
      pos 4455
      pos 4671
      pos 4804
      pos 4821
      pos 4871
      pos 4913
      pos 5037
      pos 5097
      pos 5115
      pos 5128
      pos 5140
      pos 5156
      pos 5265
      pos 5279
      pos 5288
      pos 5317
      pos 5432
      pos 5458
      pos 5571
      pos 5626
      pos 5737
      pos 5801
      pos 5865
      pos 5878
      pos 5936
      pos 6057
      pos 6080
      pos 6086
      pos 6102
      pos 6113
      pos 6120
      pos 6158
      pos 6254
      pos 6305
      pos 6315
      pos 6348
      pos 6397
      pos 6412
      pos 6424
      pos 6458
      pos 6506
      pos 6522
      pos 6538
      pos 6584
      pos 6619
      pos 6641
      pos 6651
      pos 6660
      pos 6695
      pos 6768
      pos 6860
      pos 6989
      pos 7037
      pos 7079
      pos 7090
      pos 7105
      pos 7178
      pos 7323
      pos 7330
      pos 7333
      pos 7336
      pos 7351
      pos 7367
      pos 7381
      pos 7467
      pos 7512
      pos 7568
      pos 7618
      pos 7623
      pos 7640
      pos 7738
      pos 7855
      pos 8005
      pos 8042
      pos 8091
      pos 8160
      pos 8163
      pos 8256
      pos 8328
      pos 8359
      pos 8366
      pos 8432
      pos 8436
      pos 8497
      pos 8566
      pos 8606
      pos 8745
      pos 8835
      pos 8918
      pos 9040
      pos 9057
      pos 9069
      pos 9173
      pos 9222
      pos 9267
      pos 9349
      pos 9352
      pos 9366
      pos 9384
      pos 9393
      pos 9404
      pos 9497
      pos 9506
      pos 9525
      pos 9533
      pos 9761
      pos 9778
      pos 9788
      pos 9793
      pos 9837
      pos 9846
      pos 10640
      pos 10709
      pos 10760
      pos 10762
      pos 10777
      pos 10801
      pos 10812
      pos 10831
      pos 10840
      pos 10851
      pos 10892
      pos 10894
      pos 10915
      pos 10923
    doc 12
      freq 233
      pos 96
      pos 127
      pos 480
      pos 522
      pos 552
      pos 561
      pos 570
      pos 616
      pos 643
      pos 718
      pos 845
      pos 883
      pos 908
      pos 945
      pos 1027
      pos 1074
      pos 1088
      pos 1114
      pos 1125
      pos 1201
      pos 1315
      pos 1351
      pos 1379
      pos 1413
      pos 1440
      pos 1446
      pos 1467
      pos 1473
      pos 1573
      pos 1610
      pos 1643
      pos 1662
      pos 1707
      pos 1723
      pos 1764
      pos 1795
      pos 1832
      pos 1838
      pos 1851
      pos 1859
      pos 1890
      pos 1925
      pos 1934
      pos 1965
      pos 1974
      pos 1976
      pos 1979
      pos 1998
      pos 2045
      pos 2055
      pos 2073
      pos 2104
      pos 2115
      pos 2131
      pos 2135
      pos 2165
      pos 2174
      pos 2221
      pos 2226
      pos 2256
      pos 2322
      pos 2357
      pos 2415
      pos 2421
      pos 2477
      pos 2489
      pos 2534
      pos 2548
      pos 2572
      pos 2603
      pos 2625
      pos 2774
      pos 2783
      pos 2966
      pos 2973
      pos 3054
      pos 3074
      pos 3138
      pos 3176
      pos 3235
      pos 3237
      pos 3321
      pos 3335
      pos 3405
      pos 3414
      pos 3487
      pos 3526
      pos 3539
      pos 3579
      pos 3623
      pos 3646
      pos 3655
      pos 3681
      pos 3696
      pos 3713
      pos 3733
      pos 3751
      pos 3759
      pos 3765
      pos 3803
      pos 3997
      pos 4071
      pos 4119
      pos 4158
      pos 4161
      pos 4182
      pos 4214
      pos 4225
      pos 4233
      pos 4241
      pos 4270
      pos 4295
      pos 4298
      pos 4300
      pos 4364
      pos 4442
      pos 4515
      pos 4664
      pos 4703
      pos 4713
      pos 4750
      pos 4786
      pos 4818
      pos 4837
      pos 4913
      pos 4944
      pos 4967
      pos 4995
      pos 5064
      pos 5088
      pos 5094
      pos 5127
      pos 5139
      pos 5147
      pos 5155
      pos 5161
      pos 5183
      pos 5202
      pos 5243
      pos 5289
      pos 5295
      pos 5334
      pos 5336
      pos 5384
      pos 5403
      pos 5469
      pos 5527
      pos 5564
      pos 5606
      pos 5614
      pos 5627
      pos 5700
      pos 5717
      pos 5782
      pos 5795
      pos 5799
      pos 5802
      pos 5810
      pos 5920
      pos 5963
      pos 6050
      pos 6061
      pos 6094
      pos 6122
      pos 6218
      pos 6230
      pos 6237
      pos 6278
      pos 6327
      pos 6368
      pos 6373
      pos 6454
      pos 6505
      pos 6535
      pos 6540
      pos 6559
      pos 6615
      pos 6660
      pos 6682
      pos 6728
      pos 6732
      pos 6926
      pos 6940
      pos 7041
      pos 7271
      pos 7665
      pos 7669
      pos 7683
      pos 7687
      pos 7945
      pos 7971
      pos 7978
      pos 7982
      pos 8003
      pos 8104
      pos 8409
      pos 8473
      pos 8491
      pos 8575
      pos 8594
      pos 8616
      pos 8647
      pos 8682
      pos 8697
      pos 8716
      pos 8795
      pos 8811
      pos 8839
      pos 8846
      pos 8892
      pos 8957
      pos 9197
      pos 9223
      pos 9275
      pos 9278
      pos 9289
      pos 9313
      pos 9329
      pos 9407
      pos 9490
      pos 9559
      pos 9610
      pos 9612
      pos 9627
      pos 9651
      pos 9662
      pos 9681
      pos 9690
      pos 9701
      pos 9742
      pos 9744
      pos 9765
      pos 9773
    doc 13
      freq 219
      pos 103
      pos 175
      pos 480
      pos 484
      pos 568
      pos 617
      pos 635
      pos 675
      pos 683
      pos 695
      pos 700
      pos 716
      pos 736
      pos 771
      pos 776
      pos 880
      pos 894
      pos 955
      pos 980
      pos 995
      pos 999
      pos 1012
      pos 1041
      pos 1045
      pos 1064
      pos 1104
      pos 1203
      pos 1225
      pos 1289
      pos 1295
      pos 1351
      pos 1449
      pos 1516
      pos 1640
      pos 1696
      pos 1717
      pos 1723
      pos 1747
      pos 1804
      pos 1839
      pos 1856
      pos 1875
      pos 1904
      pos 1916
      pos 1939
      pos 1989
      pos 1996
      pos 2014
      pos 2048
      pos 2053
      pos 2056
      pos 2127
      pos 2133
      pos 2161
      pos 2180
      pos 2183
      pos 2239
      pos 2241
      pos 2340
      pos 2356
      pos 2438
      pos 2586
      pos 2697
      pos 2710
      pos 2721
      pos 2737
      pos 2766
      pos 2831
      pos 2886
      pos 2944
      pos 3035
      pos 3043
      pos 3049
      pos 3102
      pos 3111
      pos 3118
      pos 3133
      pos 3179
      pos 3187
      pos 3217
      pos 3277
      pos 3354
      pos 3368
      pos 3394
      pos 3404
      pos 3415
      pos 3458
      pos 3494
      pos 3536
      pos 3546
      pos 3606
      pos 3684
      pos 3703
      pos 3718
      pos 3730
      pos 3746
      pos 3774
      pos 3781
      pos 3849
      pos 3862
      pos 3983
      pos 3990
      pos 4005
      pos 4027
      pos 4054
      pos 4079
      pos 4083
      pos 4095
      pos 4103
      pos 4131
      pos 4144
      pos 4156
      pos 4253
      pos 4257
      pos 4352
      pos 4355
      pos 4368
      pos 4401
      pos 4433
      pos 4481
      pos 4520
      pos 4570
      pos 4622
      pos 4634
      pos 4713
      pos 4772
      pos 4799
      pos 4820
      pos 4845
      pos 4875
      pos 4906
      pos 4918
      pos 4994
      pos 5058
      pos 5068
      pos 5089
      pos 5094
      pos 5115
      pos 5119
      pos 5177
      pos 5241
      pos 5249
      pos 5264
      pos 5323
      pos 5363
      pos 5397
      pos 5406
      pos 5422
      pos 5493
      pos 5509
      pos 5529
      pos 5561
      pos 5658
      pos 5675
      pos 5686
      pos 5751
      pos 5756
      pos 5769
      pos 5795
      pos 5809
      pos 5819
      pos 5836
      pos 5862
      pos 5876
      pos 5902
      pos 5928
      pos 5958
      pos 5970
      pos 5985
      pos 6029
      pos 6063
      pos 6067
      pos 6069
      pos 6085
      pos 6095
      pos 6099
      pos 6114
      pos 6119
      pos 6123
      pos 6149
      pos 6156
      pos 6189
      pos 6205
      pos 6209
      pos 6219
      pos 6224
      pos 6240
      pos 6259
      pos 6276
      pos 6279
      pos 6287
      pos 6306
      pos 6350
      pos 6402
      pos 6421
      pos 6433
      pos 6444
      pos 6522
      pos 6531
      pos 6543
      pos 6577
      pos 6638
      pos 6690
      pos 6744
      pos 6958
      pos 7105
      pos 7174
      pos 7225
      pos 7227
      pos 7242
      pos 7266
      pos 7277
      pos 7296
      pos 7305
      pos 7316
      pos 7357
      pos 7359
      pos 7380
      pos 7388
    doc 14
      freq 85
      pos 102
      pos 335
      pos 346
      pos 418
      pos 423
      pos 486
      pos 550
      pos 592
      pos 600
      pos 607
      pos 614
      pos 659
      pos 676
      pos 692
      pos 739
      pos 770
      pos 803
      pos 829
      pos 869
      pos 907
      pos 944
      pos 987
      pos 994
      pos 1031
      pos 1041
      pos 1060
      pos 1106
      pos 1350
      pos 1386
      pos 1430
      pos 1461
      pos 1522
      pos 1563
      pos 1606
      pos 1639
      pos 1646
      pos 1683
      pos 1693
      pos 1712
      pos 1752
      pos 1793
      pos 1849
      pos 1901
      pos 1934
      pos 1977
      pos 1993
      pos 2065
      pos 2094
      pos 2101
      pos 2126
      pos 2277
      pos 2280
      pos 2379
      pos 2412
      pos 2487
      pos 2570
      pos 2657
      pos 2685
      pos 2737
      pos 2794
      pos 2924
      pos 3565
      pos 3863
      pos 4533
      pos 4609
      pos 5041
      pos 5177
      pos 5310
      pos 5332
      pos 5341
      pos 5397
      pos 5571
      pos 5640
      pos 5691
      pos 5693
      pos 5708
      pos 5732
      pos 5743
      pos 5762
      pos 5771
      pos 5782
      pos 5823
      pos 5825
      pos 5846
      pos 5854
    doc 15
      freq 112
      pos 91
      pos 147
      pos 175
      pos 183
      pos 337
      pos 367
      pos 374
      pos 405
      pos 465
      pos 476
      pos 532
      pos 606
      pos 721
      pos 749
      pos 755
      pos 797
      pos 827
      pos 830
      pos 866
      pos 903
      pos 906
      pos 914
      pos 947
      pos 969
      pos 997
      pos 1061
      pos 1082
      pos 1171
      pos 1243
      pos 1291
      pos 1308
      pos 1333
      pos 1360
      pos 1435
      pos 1452
      pos 1496
      pos 1567
      pos 1591
      pos 1626
      pos 1703
      pos 1718
      pos 1779
      pos 1799
      pos 1808
      pos 1831
      pos 1901
      pos 1961
      pos 2162
      pos 2183
      pos 2219
      pos 2223
      pos 2261
      pos 2284
      pos 2296
      pos 2299
      pos 2302
      pos 2333
      pos 2347
      pos 2430
      pos 2445
      pos 2461
      pos 2472
      pos 2573
      pos 2608
      pos 2618
      pos 2634
      pos 2666
      pos 2702
      pos 2710
      pos 2714
      pos 2774
      pos 2777
      pos 2824
      pos 2838
      pos 2856
      pos 2889
      pos 2968
      pos 2970
      pos 2983
      pos 3139
      pos 3142
      pos 3166
      pos 3201
      pos 3207
      pos 3267
      pos 3280
      pos 3323
      pos 3422
      pos 3442
      pos 3465
      pos 3508
      pos 3581
      pos 3606
      pos 3696
      pos 3756
      pos 3840
      pos 3883
      pos 3892
      pos 4090
      pos 4159
      pos 4210
      pos 4212
      pos 4227
      pos 4251
      pos 4262
      pos 4281
      pos 4290
      pos 4301
      pos 4342
      pos 4344
      pos 4365
      pos 4373
    doc 16
      freq 68
      pos 51
      pos 90
      pos 101
      pos 104
      pos 149
      pos 159
      pos 179
      pos 190
      pos 216
      pos 223
      pos 293
      pos 315
      pos 324
      pos 348
      pos 390
      pos 400
      pos 425
      pos 431
      pos 478
      pos 481
      pos 491
      pos 524
      pos 578
      pos 605
      pos 643
      pos 683
      pos 738
      pos 774
      pos 808
      pos 843
      pos 863
      pos 1014
      pos 1041
      pos 1054
      pos 1108
      pos 1260
      pos 1297
      pos 1306
      pos 1368
      pos 1378
      pos 1392
      pos 1578
      pos 1591
      pos 1679
      pos 1762
      pos 1765
      pos 1875
      pos 1929
      pos 2007
      pos 2133
      pos 2274
      pos 2295
      pos 2375
      pos 2629
      pos 2701
      pos 2770
      pos 2821
      pos 2823
      pos 2838
      pos 2862
      pos 2873
      pos 2892
      pos 2901
      pos 2912
      pos 2953
      pos 2955
      pos 2976
      pos 2984
    doc 17
      freq 56
      pos 48
      pos 100
      pos 112
      pos 116
      pos 126
      pos 143
      pos 183
      pos 227
      pos 236
      pos 244
      pos 287
      pos 316
      pos 379
      pos 397
      pos 402
      pos 562
      pos 583
      pos 743
      pos 749
      pos 934
      pos 962
      pos 1017
      pos 1067
      pos 1182
      pos 1313
      pos 1408
      pos 1417
      pos 1467
      pos 1488
      pos 1510
      pos 1553
      pos 1657
      pos 1678
      pos 1695
      pos 1733
      pos 1789
      pos 1792
      pos 1807
      pos 1870
      pos 1911
      pos 1976
      pos 2036
      pos 2425
      pos 2494
      pos 2545
      pos 2547
      pos 2562
      pos 2586
      pos 2597
      pos 2616
      pos 2625
      pos 2636
      pos 2677
      pos 2679
      pos 2700
      pos 2708
    doc 18
      freq 66
      pos 57
      pos 97
      pos 228
      pos 261
      pos 303
      pos 366
      pos 402
      pos 423
      pos 429
      pos 446
      pos 493
      pos 525
      pos 544
      pos 566
      pos 578
      pos 613
      pos 668
      pos 705
      pos 746
      pos 843
      pos 900
      pos 910
      pos 941
      pos 946
      pos 959
      pos 1079
      pos 1178
      pos 1192
      pos 1227
      pos 1256
      pos 1277
      pos 1292
      pos 1308
      pos 1319
      pos 1346
      pos 1361
      pos 1602
      pos 1664
      pos 1682
      pos 1692
      pos 1706
      pos 1739
      pos 1746
      pos 1760
      pos 1792
      pos 1852
      pos 1884
      pos 1923
      pos 2000
      pos 2007
      pos 2040
      pos 2135
      pos 2213
      pos 2282
      pos 2333
      pos 2335
      pos 2350
      pos 2374
      pos 2385
      pos 2404
      pos 2413
      pos 2424
      pos 2465
      pos 2467
      pos 2488
      pos 2496
    skipList 
      level 0
        skipDoc 7
        skipDocFP 2433771
        impacts 
          impact 
            freq 73
            norm 100
          impact 
            freq 87
            norm 101
          impact 
            freq 121
            norm 104
          impact 
            freq 140
            norm 107
          impact 
            freq 183
            norm 108
          impact 
            freq 237
            norm 113
        impactsEnd 
        skipDoc 15
        skipDocFP 2452481
        impacts 
          impact 
            freq 62
            norm 95
          impact 
            freq 112
            norm 104
          impact 
            freq 219
            norm 109
          impact 
            freq 233
            norm 113
          impact 
            freq 307
            norm 116
        impactsEnd 
  term tob
    doc 1
      freq 1
      pos 9588
  term toby
    doc 1
      freq 1
      pos 9572
  term tocmz
    doc 11
      freq 1
      pos 10143
  term today
    doc 2
      freq 1
      pos 3894
    doc 7
      freq 1
      pos 92
    doc 10
      freq 5
      pos 550
      pos 612
      pos 668
      pos 854
      pos 9711
    doc 12
      freq 1
      pos 4960
    doc 15
      freq 1
      pos 2867
    doc 16
      freq 1
      pos 2386
  term todd
    doc 6
      freq 1
      pos 3096
  term together
    doc 1
      freq 4
      pos 2738
      pos 2876
      pos 3515
      pos 3528
    doc 2
      freq 1
      pos 4444
  term toggl
    doc 12
      freq 1
      pos 3399
  term token
    doc 4
      freq 3
      pos 1895
      pos 1992
      pos 5602
    doc 7
      freq 4
      pos 868
      pos 974
      pos 2278
      pos 2426
    doc 9
      freq 2
      pos 740
      pos 750
    doc 10
      freq 6
      pos 4845
      pos 5149
      pos 8046
      pos 8150
      pos 8155
      pos 11161
    doc 11
      freq 11
      pos 353
      pos 1616
      pos 1665
      pos 1711
      pos 1728
      pos 1752
      pos 1841
      pos 2634
      pos 2776
      pos 6490
      pos 6513
  term token1
    doc 11
      freq 1
      pos 1967
  term token2
    doc 11
      freq 1
      pos 1968
  term token3
    doc 11
      freq 1
      pos 1969
  term tokens
    doc 9
      freq 3
      pos 724
      pos 753
      pos 783
    doc 10
      freq 2
      pos 5096
      pos 5106
    doc 11
      freq 1
      pos 1698
  term toleranc
    doc 6
      freq 1
      pos 2676
    doc 13
      freq 1
      pos 2160
  term tolerant
    doc 5
      freq 4
      pos 22
      pos 92
      pos 4198
      pos 4223
  term tolerat
    doc 13
      freq 1
      pos 5010
  term tolerates
    doc 5
      freq 1
      pos 121
  term tolerating
    doc 6
      freq 1
      pos 2640
  term tom
    doc 11
      freq 2
      pos 9494
      pos 9599
  term toni
    doc 13
      freq 1
      pos 6973
  term tony
    doc 2
      freq 2
      pos 3465
      pos 4476
  term too
    doc 0
      freq 4
      pos 3635
      pos 4151
      pos 10993
      pos 12520
    doc 2
      freq 2
      pos 1136
      pos 4555
    doc 4
      freq 10
      pos 193
      pos 771
      pos 1680
      pos 1746
      pos 1781
      pos 2755
      pos 2859
      pos 2907
      pos 2977
      pos 3165
    doc 5
      freq 1
      pos 652
    doc 7
      freq 1
      pos 1278
    doc 10
      freq 3
      pos 2798
      pos 9971
      pos 10361
    doc 11
      freq 1
      pos 8579
    doc 12
      freq 6
      pos 8105
      pos 8430
      pos 8464
      pos 9284
      pos 9298
      pos 9383
    doc 13
      freq 1
      pos 749
    skipList 
      level 0
        skipDoc 12
        skipDocFP 2477081
        impacts 
          impact 
            freq 1
            norm 100
          impact 
            freq 10
            norm 108
        impactsEnd 
  term toobig
    doc 16
      freq 8
      pos 595
      pos 1321
      pos 1324
      pos 1364
      pos 1395
      pos 1500
      pos 1506
      pos 1509
  term took
    doc 2
      freq 6
      pos 803
      pos 3549
      pos 3653
      pos 3746
      pos 3989
      pos 4732
  term tool
    doc 2
      freq 2
      pos 569
      pos 583
    doc 6
      freq 1
      pos 192
    doc 13
      freq 1
      pos 6796
  term tools
    doc 6
      freq 1
      pos 2593
    doc 13
      freq 1
      pos 454
    doc 14
      freq 1
      pos 2118
  term top
    doc 0
      freq 1
      pos 1250
    doc 1
      freq 1
      pos 8157
    doc 7
      freq 1
      pos 263
    doc 10
      freq 1
      pos 11124
    doc 13
      freq 1
      pos 923
    doc 16
      freq 1
      pos 1890
  term topic
    doc 10
      freq 1
      pos 2232
    doc 12
      freq 1
      pos 4211
  term topjgat37
    doc 10
      freq 1
      pos 12471
  term topmost
    doc 10
      freq 3
      pos 8852
      pos 8895
      pos 8911
  term topological
    doc 12
      freq 3
      pos 4974
      pos 5209
      pos 5374
    doc 15
      freq 1
      pos 1988
  term topology
    doc 0
      freq 4
      pos 1533
      pos 16066
      pos 16395
      pos 16595
    doc 3
      freq 1
      pos 3423
  term tortuous
    doc 11
      freq 2
      pos 139
      pos 1202
  term tortur
    doc 10
      freq 1
      pos 13396
    doc 11
      freq 54
      pos 35
      pos 91
      pos 192
      pos 495
      pos 822
      pos 1048
      pos 1255
      pos 1441
      pos 1575
      pos 1899
      pos 2113
      pos 2293
      pos 2545
      pos 2786
      pos 3054
      pos 3321
      pos 3444
      pos 3689
      pos 3885
      pos 3986
      pos 4172
      pos 4412
      pos 4655
      pos 4893
      pos 5071
      pos 5238
      pos 5395
      pos 5543
      pos 5703
      pos 5835
      pos 6023
      pos 6247
      pos 6483
      pos 6719
      pos 6933
      pos 7143
      pos 7271
      pos 7549
      pos 7783
      pos 8030
      pos 8227
      pos 8459
      pos 8643
      pos 8862
      pos 8961
      pos 9206
      pos 9416
      pos 9723
      pos 9861
      pos 10027
      pos 10217
      pos 10426
      pos 10519
      pos 10622
  term total
    doc 0
      freq 3
      pos 3622
      pos 4138
      pos 10979
    doc 5
      freq 1
      pos 1725
    doc 9
      freq 1
      pos 515
    doc 14
      freq 1
      pos 2359
    doc 18
      freq 1
      pos 1575
  term touch
    doc 13
      freq 1
      pos 2756
  term touched
    doc 15
      freq 1
      pos 497
  term toward
    doc 9
      freq 1
      pos 881
  term towards
    doc 3
      freq 1
      pos 3856
    doc 13
      freq 1
      pos 539
  term township
    doc 1
      freq 1
      pos 9584
  term townsley
    doc 3
      freq 2
      pos 4632
      pos 4716
    doc 8
      freq 1
      pos 1835
  term tp
    doc 10
      freq 1
      pos 6222
  term tpcp3kwzlshyhjpmbcghxzep1cnli0nalzdxhpxtudlseflngfqgbrcgy9ccd97w
    doc 10
      freq 1
      pos 12544
  term tplpj6gscy
    doc 11
      freq 1
      pos 10485
  term tpr8vtj2ofxr0slknhgrqm6dav9h
    doc 10
      freq 1
      pos 12814
  term tpwwbxt
    doc 11
      freq 1
      pos 9963
  term tr
    doc 2
      freq 1
      pos 2871
  term tr9577
    doc 0
      freq 1
      pos 1684
  term tracerout
    doc 4
      freq 1
      pos 1953
  term track
    doc 0
      freq 110
      pos 14
      pos 38
      pos 182
      pos 483
      pos 657
      pos 818
      pos 990
      pos 1199
      pos 1397
      pos 1609
      pos 1775
      pos 1916
      pos 2092
      pos 2324
      pos 2534
      pos 2715
      pos 2894
      pos 3082
      pos 3243
      pos 3454
      pos 3666
      pos 3801
      pos 4012
      pos 4197
      pos 4400
      pos 4437
      pos 4543
      pos 4700
      pos 4816
      pos 5038
      pos 5232
      pos 5469
      pos 5583
      pos 5765
      pos 5946
      pos 6174
      pos 6339
      pos 6429
      pos 6649
      pos 6903
      pos 7082
      pos 7194
      pos 7246
      pos 7347
      pos 7509
      pos 7674
      pos 7736
      pos 7813
      pos 7947
      pos 8131
      pos 8251
      pos 8326
      pos 8416
      pos 8635
      pos 8823
      pos 8923
      pos 9075
      pos 9240
      pos 9434
      pos 9590
      pos 9734
      pos 9900
      pos 10040
      pos 10166
      pos 10380
      pos 10579
      pos 10805
      pos 11017
      pos 11091
      pos 11299
      pos 11480
      pos 11638
      pos 11769
      pos 11875
      pos 12046
      pos 12173
      pos 12309
      pos 12462
      pos 12634
      pos 12782
      pos 12820
      pos 12987
      pos 13178
      pos 13337
      pos 13537
      pos 13731
      pos 13921
      pos 14132
      pos 14319
      pos 14496
      pos 14662
      pos 14800
      pos 14920
      pos 15047
      pos 15174
      pos 15304
      pos 15415
      pos 15486
      pos 15557
      pos 15635
      pos 15719
      pos 15796
      pos 16128
      pos 16317
      pos 16469
      pos 16602
      pos 16840
      pos 17098
      pos 17213
      pos 17544
    doc 1
      freq 35
      pos 14
      pos 55
      pos 201
      pos 424
      pos 832
      pos 1061
      pos 1369
      pos 1862
      pos 2222
      pos 2418
      pos 2692
      pos 3051
      pos 3421
      pos 3606
      pos 3903
      pos 4240
      pos 4634
      pos 5014
      pos 5293
      pos 5685
      pos 6020
      pos 6361
      pos 6756
      pos 7194
      pos 7636
      pos 7886
      pos 8234
      pos 8702
      pos 9017
      pos 9221
      pos 9328
      pos 9398
      pos 9493
      pos 9594
      pos 9927
    doc 2
      freq 3
      pos 1931
      pos 3761
      pos 4316
    doc 3
      freq 26
      pos 14
      pos 49
      pos 164
      pos 329
      pos 576
      pos 756
      pos 1035
      pos 1421
      pos 1774
      pos 2113
      pos 2424
      pos 2819
      pos 3203
      pos 3612
      pos 4006
      pos 4294
      pos 4555
      pos 4736
      pos 4829
      pos 4933
      pos 4998
      pos 5194
      pos 5584
      pos 5785
      pos 5941
      pos 6276
    doc 4
      freq 27
      pos 20
      pos 51
      pos 137
      pos 418
      pos 738
      pos 1007
      pos 1364
      pos 1751
      pos 2073
      pos 2310
      pos 2714
      pos 2960
      pos 3197
      pos 3433
      pos 3623
      pos 3795
      pos 4085
      pos 4495
      pos 4826
      pos 4881
      pos 5152
      pos 5397
      pos 5527
      pos 5812
      pos 6031
      pos 6097
      pos 6431
    doc 5
      freq 20
      pos 13
      pos 35
      pos 245
      pos 348
      pos 784
      pos 1141
      pos 1472
      pos 1739
      pos 2042
      pos 2353
      pos 2550
      pos 2731
      pos 3045
      pos 3355
      pos 3656
      pos 3908
      pos 4108
      pos 4344
      pos 4429
      pos 4760
    doc 9
      freq 11
      pos 14
      pos 37
      pos 227
      pos 590
      pos 901
      pos 931
      pos 1367
      pos 1452
      pos 1722
      pos 1793
      pos 2126
    doc 10
      freq 47
      pos 12
      pos 40
      pos 169
      pos 393
      pos 784
      pos 1247
      pos 1698
      pos 2085
      pos 2511
      pos 2966
      pos 3370
      pos 3782
      pos 4181
      pos 4592
      pos 4936
      pos 5396
      pos 5469
      pos 5749
      pos 5761
      pos 6051
      pos 6269
      pos 6522
      pos 6777
      pos 6963
      pos 7267
      pos 7597
      pos 8029
      pos 8463
      pos 8983
      pos 9473
      pos 9938
      pos 10328
      pos 10784
      pos 11201
      pos 11539
      pos 11834
      pos 12002
      pos 12086
      pos 12091
      pos 12382
      pos 12529
      pos 12693
      pos 12828
      pos 13078
      pos 13328
      pos 13457
      pos 13788
    doc 16
      freq 16
      pos 18
      pos 36
      pos 164
      pos 530
      pos 905
      pos 1310
      pos 1565
      pos 1649
      pos 1684
      pos 1852
      pos 2110
      pos 2247
      pos 2509
      pos 2638
      pos 2678
      pos 3009
    doc 17
      freq 13
      pos 12
      pos 33
      pos 152
      pos 511
      pos 811
      pos 1049
      pos 1395
      pos 1844
      pos 2109
      pos 2147
      pos 2316
      pos 2402
      pos 2734
    doc 18
      freq 10
      pos 18
      pos 42
      pos 242
      pos 618
      pos 1026
      pos 1381
      pos 1808
      pos 2148
      pos 2191
      pos 2522
    skipList 
      level 0
        skipDoc 10
        skipDocFP 2481358
        impacts 
          impact 
            freq 11
            norm 95
          impact 
            freq 20
            norm 104
          impact 
            freq 26
            norm 107
          impact 
            freq 27
            norm 108
          impact 
            freq 35
            norm 113
          impact 
            freq 47
            norm 116
          impact 
            freq 110
            norm 120
        impactsEnd 
  term tracked
    doc 2
      freq 1
      pos 5471
  term tracks
    doc 0
      freq 1
      pos 4489
  term trade
    doc 12
      freq 2
      pos 8984
      pos 9032
  term tradeoffs
    doc 12
      freq 1
      pos 7242
  term traditional
    doc 2
      freq 1
      pos 1743
    doc 13
      freq 1
      pos 724
  term traditionally
    doc 11
      freq 1
      pos 9373
  term traffic
    doc 0
      freq 16
      pos 1766
      pos 1810
      pos 5211
      pos 8285
      pos 8314
      pos 16011
      pos 16016
      pos 16032
      pos 16040
      pos 16230
      pos 16368
      pos 16413
      pos 16423
      pos 16438
      pos 16629
      pos 16684
    doc 1
      freq 3
      pos 605
      pos 682
      pos 8388
    doc 2
      freq 2
      pos 3004
      pos 3398
    doc 3
      freq 3
      pos 2385
      pos 2409
      pos 3467
    doc 4
      freq 6
      pos 1951
      pos 2669
      pos 4078
      pos 4474
      pos 4524
      pos 4534
    doc 5
      freq 5
      pos 324
      pos 986
      pos 2942
      pos 3080
      pos 3559
    doc 6
      freq 12
      pos 229
      pos 1201
      pos 1213
      pos 1354
      pos 1435
      pos 1547
      pos 2228
      pos 2234
      pos 2282
      pos 2308
      pos 2403
      pos 2734
    doc 7
      freq 2
      pos 690
      pos 1986
    doc 9
      freq 2
      pos 518
      pos 1510
    doc 12
      freq 1
      pos 5759
    skipList 
      level 0
        skipDoc 7
        skipDocFP 2487308
        impacts 
          impact 
            freq 2
            norm 100
          impact 
            freq 12
            norm 101
          impact 
            freq 16
            norm 120
        impactsEnd 
  term trailers
    doc 13
      freq 2
      pos 3562
      pos 3611
  term trailing
    doc 11
      freq 2
      pos 206
      pos 3204
  term trans
    doc 14
      freq 2
      pos 312
      pos 5488
  term transaction
    doc 10
      freq 3
      pos 5962
      pos 8653
      pos 8698
    doc 11
      freq 7
      pos 386
      pos 392
      pos 7002
      pos 7015
      pos 7020
      pos 7030
      pos 7095
    doc 17
      freq 1
      pos 760
  term transactions
    doc 13
      freq 1
      pos 4012
  term transceiver
    doc 13
      freq 5
      pos 1375
      pos 1378
      pos 5916
      pos 6305
      pos 6502
  term transceivers
    doc 13
      freq 2
      pos 6129
      pos 6378
  term transfer
    doc 1
      freq 1
      pos 114
    doc 2
      freq 2
      pos 1366
      pos 2827
    doc 7
      freq 2
      pos 1908
      pos 2865
    doc 11
      freq 3
      pos 3830
      pos 3862
      pos 3873
    doc 12
      freq 1
      pos 7103
    doc 13
      freq 9
      pos 2096
      pos 2121
      pos 2465
      pos 5302
      pos 5488
      pos 5537
      pos 5548
      pos 5554
      pos 6898
    doc 16
      freq 4
      pos 1119
      pos 1161
      pos 2039
      pos 2217
  term transferred
    doc 2
      freq 1
      pos 1361
  term transferring
    doc 2
      freq 1
      pos 2830
  term transfers
    doc 13
      freq 2
      pos 1337
      pos 2451
    doc 14
      freq 1
      pos 2482
    doc 18
      freq 1
      pos 284
  term transform
    doc 5
      freq 2
      pos 1086
      pos 4204
    doc 7
      freq 2
      pos 1141
      pos 2730
  term transformations
    doc 10
      freq 2
      pos 6175
      pos 12201
  term transformed
    doc 10
      freq 2
      pos 5026
      pos 8678
  term transforming
    doc 2
      freq 1
      pos 3751
  term transient
    doc 6
      freq 3
      pos 2396
      pos 2436
      pos 2503
  term transit
    doc 1
      freq 1
      pos 8360
    doc 4
      freq 1
      pos 3084
    doc 5
      freq 1
      pos 389
  term transition
    doc 6
      freq 1
      pos 2615
    doc 12
      freq 6
      pos 207
      pos 1501
      pos 1512
      pos 7363
      pos 7578
      pos 7595
    doc 14
      freq 1
      pos 5498
    doc 15
      freq 1
      pos 3580
  term transitional
    doc 6
      freq 1
      pos 495
    doc 10
      freq 3
      pos 302
      pos 11006
      pos 11232
  term transitiv
    doc 10
      freq 3
      pos 1385
      pos 1413
      pos 1445
  term translated
    doc 11
      freq 1
      pos 5916
  term translation
    doc 10
      freq 1
      pos 3444
    doc 12
      freq 4
      pos 1604
      pos 7479
      pos 7481
      pos 9231
  term translations
    doc 12
      freq 1
      pos 7618
  term transmission
    doc 0
      freq 4
      pos 5802
      pos 7036
      pos 7115
      pos 16555
    doc 1
      freq 4
      pos 456
      pos 583
      pos 634
      pos 6153
    doc 3
      freq 1
      pos 3855
    doc 4
      freq 2
      pos 1902
      pos 2849
    doc 7
      freq 2
      pos 1843
      pos 2564
    doc 13
      freq 1
      pos 3025
  term transmissions
    doc 0
      freq 1
      pos 6997
  term transmit
    doc 1
      freq 2
      pos 524
      pos 919
    doc 3
      freq 1
      pos 1113
    doc 6
      freq 1
      pos 2226
    doc 8
      freq 2
      pos 1610
      pos 1628
  term transmitted
    doc 0
      freq 2
      pos 6543
      pos 6812
    doc 1
      freq 6
      pos 860
      pos 876
      pos 1150
      pos 1364
      pos 7963
      pos 8277
    doc 3
      freq 3
      pos 805
      pos 1911
      pos 2208
    doc 4
      freq 1
      pos 1929
    doc 5
      freq 2
      pos 1188
      pos 2276
    doc 6
      freq 1
      pos 1277
    doc 13
      freq 2
      pos 1255
      pos 4551
  term transmitting
    doc 1
      freq 4
      pos 135
      pos 488
      pos 6166
      pos 8266
    doc 3
      freq 2
      pos 2755
      pos 3710
  term transparency
    doc 3
      freq 2
      pos 1452
      pos 1469
  term transparent
    doc 3
      freq 1
      pos 3883
    doc 8
      freq 1
      pos 646
  term transparently
    doc 3
      freq 2
      pos 1210
      pos 2618
    doc 12
      freq 2
      pos 2371
      pos 2418
  term transport
    doc 1
      freq 10
      pos 239
      pos 672
      pos 1196
      pos 1985
      pos 2683
      pos 8223
      pos 9038
      pos 9062
      pos 9084
      pos 9111
    doc 3
      freq 4
      pos 33
      pos 547
      pos 1347
      pos 4192
    doc 4
      freq 3
      pos 2578
      pos 2587
      pos 6018
    doc 5
      freq 9
      pos 159
      pos 291
      pos 879
      pos 1528
      pos 2474
      pos 2562
      pos 2898
      pos 4231
      pos 4369
    doc 6
      freq 9
      pos 359
      pos 441
      pos 565
      pos 821
      pos 1058
      pos 1241
      pos 2094
      pos 2832
      pos 3074
    doc 7
      freq 3
      pos 260
      pos 1033
      pos 2578
    doc 8
      freq 10
      pos 642
      pos 648
      pos 680
      pos 689
      pos 694
      pos 719
      pos 1913
      pos 1951
      pos 1973
      pos 1998
    doc 10
      freq 1
      pos 530
    doc 11
      freq 6
      pos 226
      pos 3560
      pos 3572
      pos 3577
      pos 3609
      pos 4396
    doc 12
      freq 20
      pos 163
      pos 312
      pos 346
      pos 599
      pos 875
      pos 909
      pos 956
      pos 982
      pos 996
      pos 1070
      pos 1110
      pos 1136
      pos 3161
      pos 4137
      pos 7336
      pos 8719
      pos 8764
      pos 8929
      pos 9148
      pos 9205
    doc 13
      freq 31
      pos 414
      pos 1119
      pos 1409
      pos 1437
      pos 1470
      pos 1490
      pos 1494
      pos 1503
      pos 1623
      pos 1682
      pos 1712
      pos 1851
      pos 2329
      pos 2522
      pos 2592
      pos 2673
      pos 2685
      pos 2703
      pos 3137
      pos 3156
      pos 3700
      pos 3766
      pos 3922
      pos 3931
      pos 3940
      pos 3954
      pos 5049
      pos 5110
      pos 5141
      pos 5163
      pos 6386
    doc 15
      freq 5
      pos 689
      pos 1445
      pos 2404
      pos 3375
      pos 3553
    skipList 
      level 0
        skipDoc 10
        skipDocFP 2492876
        impacts 
          impact 
            freq 10
            norm 97
        impactsEnd 
  term transported
    doc 1
      freq 4
      pos 1144
      pos 1711
      pos 1727
      pos 5214
    doc 3
      freq 3
      pos 800
      pos 1442
      pos 4091
    doc 5
      freq 2
      pos 1496
      pos 1989
  term transporting
    doc 1
      freq 3
      pos 565
      pos 654
      pos 6185
    doc 5
      freq 1
      pos 1509
  term transports
    doc 3
      freq 1
      pos 1373
    doc 11
      freq 1
      pos 3612
    doc 13
      freq 2
      pos 517
      pos 1442
  term transports.kijh4akdnaqjkwendsasfdj
    doc 11
      freq 1
      pos 3631
  term transwitch
    doc 4
      freq 2
      pos 9
      pos 6046
  term traps
    doc 0
      freq 1
      pos 16522
  term travel
    doc 1
      freq 1
      pos 538
    doc 2
      freq 1
      pos 1174
    doc 16
      freq 1
      pos 2045
  term traveling
    doc 1
      freq 1
      pos 7517
  term traversing
    doc 3
      freq 1
      pos 3026
  term treat
    doc 1
      freq 2
      pos 6935
      pos 7975
    doc 11
      freq 6
      pos 1352
      pos 2134
      pos 4842
      pos 7468
      pos 7592
      pos 7924
  term treated
    doc 12
      freq 1
      pos 8549
    doc 14
      freq 2
      pos 1922
      pos 2334
  term treatment
    doc 12
      freq 1
      pos 5880
  term tree
    doc 2
      freq 3
      pos 3594
      pos 3617
      pos 4722
    doc 3
      freq 1
      pos 1734
    doc 12
      freq 7
      pos 784
      pos 814
      pos 820
      pos 834
      pos 1309
      pos 5074
      pos 5086
  term trees
    doc 12
      freq 1
      pos 119
  term trial
    doc 2
      freq 3
      pos 1317
      pos 2399
      pos 6293
  term trials
    doc 6
      freq 1
      pos 430
  term tricc
    doc 3
      freq 1
      pos 4870
  term tried
    doc 12
      freq 3
      pos 3464
      pos 3797
      pos 9127
  term tries
    doc 11
      freq 1
      pos 693
  term triggered
    doc 0
      freq 1
      pos 12404
  term trip
    doc 16
      freq 1
      pos 2015
  term trivial
    doc 10
      freq 1
      pos 9372
    doc 13
      freq 2
      pos 5416
      pos 5438
    doc 14
      freq 1
      pos 405
  term trondheim
    doc 7
      freq 1
      pos 2927
    doc 15
      freq 1
      pos 4039
  term tropos
    doc 4
      freq 2
      pos 24
      pos 6076
  term tropos.com
    doc 4
      freq 1
      pos 6092
  term troubleshoot
    doc 6
      freq 1
      pos 1032
  term troubleshooting
    doc 6
      freq 1
      pos 1098
  term trowbridg
    doc 2
      freq 1
      pos 2249
  term trubey
    doc 6
      freq 1
      pos 3105
  term true
    doc 0
      freq 6
      pos 2780
      pos 2990
      pos 3021
      pos 5799
      pos 6207
      pos 6243
    doc 12
      freq 1
      pos 2542
    doc 15
      freq 1
      pos 1980
  term truetken
    doc 11
      freq 1
      pos 9606
  term truncated
    doc 5
      freq 1
      pos 1942
    doc 12
      freq 1
      pos 9305
  term truncation
    doc 4
      freq 2
      pos 1580
      pos 1618
  term trust
    doc 1
      freq 2
      pos 8192
      pos 8200
    doc 9
      freq 2
      pos 416
      pos 553
    doc 10
      freq 8
      pos 1414
      pos 1446
      pos 1499
      pos 1519
      pos 9200
      pos 9212
      pos 10942
      pos 10979
    doc 12
      freq 1
      pos 4751
    doc 17
      freq 1
      pos 403
  term trusted
    doc 1
      freq 3
      pos 8539
      pos 8548
      pos 8559
    doc 9
      freq 2
      pos 217
      pos 328
    doc 10
      freq 4
      pos 1459
      pos 4089
      pos 10968
      pos 13306
    doc 12
      freq 3
      pos 5468
      pos 5478
      pos 5841
    doc 17
      freq 2
      pos 1382
      pos 1869
  term trusts
    doc 17
      freq 1
      pos 1936
  term trustworthiness
    doc 9
      freq 1
      pos 665
  term trustworthy
    doc 9
      freq 1
      pos 608
  term truthvalu
    doc 0
      freq 17
      pos 1014
      pos 2771
      pos 2976
      pos 4723
      pos 4731
      pos 4964
      pos 5200
      pos 5492
      pos 5496
      pos 5502
      pos 5506
      pos 5790
      pos 5904
      pos 6080
      pos 6190
      pos 11787
      pos 11865
  term trws
    doc 11
      freq 1
      pos 5783
  term trws.oicu34958239neffasdhr2345r
    doc 11
      freq 1
      pos 5813
  term try
    doc 11
      freq 1
      pos 2150
    doc 12
      freq 1
      pos 1763
    doc 15
      freq 2
      pos 2857
      pos 2890
    doc 16
      freq 1
      pos 1377
  term trying
    doc 11
      freq 1
      pos 6583
  term ts
    doc 6
      freq 3
      pos 567
      pos 1243
      pos 1425
  term tschofenig
    doc 5
      freq 20
      pos 10
      pos 243
      pos 346
      pos 782
      pos 1139
      pos 1470
      pos 1737
      pos 2040
      pos 2351
      pos 2548
      pos 2729
      pos 3043
      pos 3353
      pos 3654
      pos 3906
      pos 4106
      pos 4342
      pos 4413
      pos 4427
      pos 4758
  term tsirtsis
    doc 12
      freq 1
      pos 7472
  term tso
    doc 3
      freq 1
      pos 4883
  term ttl
    doc 11
      freq 1
      pos 4882
    doc 12
      freq 18
      pos 289
      pos 297
      pos 304
      pos 2057
      pos 2795
      pos 2808
      pos 2895
      pos 2960
      pos 2981
      pos 3037
      pos 3067
      pos 4832
      pos 4853
      pos 4879
      pos 4904
      pos 6602
      pos 6698
      pos 6799
  term ttls
    doc 12
      freq 1
      pos 4789
  term tunnel
    doc 1
      freq 25
      pos 545
      pos 643
      pos 880
      pos 899
      pos 908
      pos 926
      pos 938
      pos 1018
      pos 1093
      pos 1095
      pos 1097
      pos 1221
      pos 1248
      pos 1261
      pos 1274
      pos 1300
      pos 1357
      pos 1384
      pos 1407
      pos 1507
      pos 1518
      pos 1780
      pos 2664
      pos 2681
      pos 8394
    doc 2
      freq 2
      pos 3058
      pos 3082
    doc 3
      freq 10
      pos 592
      pos 738
      pos 881
      pos 898
      pos 2197
      pos 2215
      pos 2235
      pos 2283
      pos 4211
      pos 4278
  term tunneled
    doc 10
      freq 1
      pos 8304
  term tunneling
    doc 3
      freq 2
      pos 4218
      pos 4723
    doc 7
      freq 2
      pos 688
      pos 1984
    doc 12
      freq 3
      pos 1404
      pos 1580
      pos 7611
  term tunnels
    doc 1
      freq 3
      pos 952
      pos 1323
      pos 1337
  term tuples
    doc 0
      freq 1
      pos 11991
  term turn
    doc 10
      freq 1
      pos 1368
    doc 12
      freq 1
      pos 682
  term turning
    doc 0
      freq 1
      pos 16520
  term tut
    doc 2
      freq 2
      pos 1901
      pos 3411
  term tut.html
    doc 2
      freq 1
      pos 3438
  term tv
    doc 13
      freq 11
      pos 203
      pos 523
      pos 557
      pos 2869
      pos 2905
      pos 2948
      pos 2960
      pos 2962
      pos 2992
      pos 3017
      pos 3081
  term tv5vzvx
    doc 11
      freq 1
      pos 10392
  term tveit
    doc 7
      freq 1
      pos 2919
  term twice
    doc 10
      freq 1
      pos 8572
    doc 16
      freq 1
      pos 404
  term twmtmt57
    doc 11
      freq 1
      pos 10462
  term two
    doc 0
      freq 3
      pos 10685
      pos 13064
      pos 13389
    doc 1
      freq 10
      pos 996
      pos 2144
      pos 2856
      pos 3076
      pos 3566
      pos 3898
      pos 3922
      pos 4781
      pos 7904
      pos 8442
    doc 2
      freq 4
      pos 102
      pos 4755
      pos 6103
      pos 6112
    doc 3
      freq 12
      pos 554
      pos 679
      pos 710
      pos 823
      pos 1126
      pos 1158
      pos 1165
      pos 1332
      pos 1341
      pos 2347
      pos 3163
      pos 4722
    doc 4
      freq 4
      pos 688
      pos 1672
      pos 1722
      pos 5097
    doc 5
      freq 5
      pos 2018
      pos 2067
      pos 2190
      pos 2992
      pos 3922
    doc 6
      freq 2
      pos 1149
      pos 1720
    doc 10
      freq 14
      pos 138
      pos 1381
      pos 4768
      pos 4792
      pos 5134
      pos 6597
      pos 7202
      pos 7313
      pos 8409
      pos 10159
      pos 10428
      pos 11468
      pos 11485
      pos 12300
    doc 11
      freq 3
      pos 2350
      pos 2484
      pos 3702
    doc 12
      freq 9
      pos 1209
      pos 1262
      pos 2304
      pos 2340
      pos 2660
      pos 2827
      pos 7939
      pos 8121
      pos 8626
    doc 13
      freq 4
      pos 1968
      pos 2061
      pos 5635
      pos 6463
    doc 14
      freq 7
      pos 72
      pos 430
      pos 915
      pos 1394
      pos 1571
      pos 2806
      pos 2854
    doc 15
      freq 13
      pos 888
      pos 892
      pos 1600
      pos 1766
      pos 1973
      pos 2458
      pos 2507
      pos 2995
      pos 3029
      pos 3485
      pos 3609
      pos 3630
      pos 3787
    doc 16
      freq 2
      pos 1204
      pos 1730
    doc 17
      freq 3
      pos 985
      pos 1099
      pos 1780
    doc 18
      freq 1
      pos 987
    skipList 
      level 0
        skipDoc 10
        skipDocFP 2502123
        impacts 
          impact 
            freq 2
            norm 101
          impact 
            freq 5
            norm 104
          impact 
            freq 12
            norm 107
          impact 
            freq 14
            norm 116
        impactsEnd 
        skipDoc 18
        skipDocFP 2503121
        impacts 
          impact 
            freq 1
            norm 97
          impact 
            freq 3
            norm 98
          impact 
            freq 13
            norm 104
        impactsEnd 
  term twofold
    doc 10
      freq 1
      pos 10048
  term txc.com
    doc 4
      freq 1
      pos 6057
  term txt
    doc 2
      freq 2
      pos 2366
      pos 2389
  term tygar
    doc 5
      freq 2
      pos 4189
      pos 4264
  term type
    doc 0
      freq 278
      pos 724
      pos 1023
      pos 1025
      pos 1407
      pos 1587
      pos 2241
      pos 2284
      pos 2319
      pos 2384
      pos 2464
      pos 2527
      pos 2608
      pos 2660
      pos 2710
      pos 2769
      pos 2803
      pos 2851
      pos 2942
      pos 2974
      pos 3033
      pos 3134
      pos 3175
      pos 3231
      pos 3350
      pos 3406
      pos 3466
      pos 3519
      pos 3589
      pos 3694
      pos 3705
      pos 3717
      pos 3754
      pos 3771
      pos 3880
      pos 3923
      pos 3953
      pos 4001
      pos 4097
      pos 4194
      pos 4217
      pos 4229
      pos 4248
      pos 4283
      pos 4380
      pos 4454
      pos 4477
      pos 4524
      pos 4557
      pos 4583
      pos 4610
      pos 4648
      pos 4670
      pos 4734
      pos 4754
      pos 4807
      pos 4863
      pos 4962
      pos 5019
      pos 5139
      pos 5168
      pos 5198
      pos 5227
      pos 5406
      pos 5431
      pos 5511
      pos 5578
      pos 5623
      pos 5645
      pos 5719
      pos 5740
      pos 5751
      pos 5758
      pos 5782
      pos 5788
      pos 5825
      pos 5837
      pos 5902
      pos 5935
      pos 6018
      pos 6078
      pos 6132
      pos 6188
      pos 6212
      pos 6272
      pos 6297
      pos 6380
      pos 6400
      pos 6441
      pos 6467
      pos 6499
      pos 6609
      pos 6719
      pos 6778
      pos 6835
      pos 6929
      pos 6976
      pos 7016
      pos 7094
      pos 7151
      pos 7201
      pos 7224
      pos 7285
      pos 7305
      pos 7377
      pos 7386
      pos 7399
      pos 7410
      pos 7443
      pos 7470
      pos 7500
      pos 7543
      pos 7570
      pos 7606
      pos 7653
      pos 7669
      pos 7704
      pos 7748
      pos 7771
      pos 7836
      pos 7853
      pos 7897
      pos 7928
      pos 7965
      pos 8006
      pos 8036
      pos 8086
      pos 8128
      pos 8162
      pos 8177
      pos 8200
      pos 8211
      pos 8268
      pos 8299
      pos 8364
      pos 8388
      pos 8413
      pos 8494
      pos 8552
      pos 8609
      pos 8666
      pos 8711
      pos 8756
      pos 8812
      pos 8847
      pos 8910
      pos 8966
      pos 8997
      pos 9050
      pos 9087
      pos 9106
      pos 9119
      pos 9145
      pos 9175
      pos 9233
      pos 9289
      pos 9319
      pos 9396
      pos 9446
      pos 9495
      pos 9529
      pos 9583
      pos 9629
      pos 9680
      pos 9711
      pos 9722
      pos 9752
      pos 9775
      pos 9820
      pos 9854
      pos 9914
      pos 9970
      pos 9996
      pos 10070
      pos 10105
      pos 10154
      pos 10195
      pos 10232
      pos 10251
      pos 10285
      pos 10467
      pos 10504
      pos 10538
      pos 10614
      pos 10712
      pos 10796
      pos 10823
      pos 10829
      pos 10839
      pos 10884
      pos 10919
      pos 11070
      pos 11081
      pos 11103
      pos 11131
      pos 11148
      pos 11244
      pos 11277
      pos 11288
      pos 11311
      pos 11329
      pos 11346
      pos 11361
      pos 11369
      pos 11379
      pos 11402
      pos 11453
      pos 11497
      pos 11530
      pos 11560
      pos 11594
      pos 11650
      pos 11708
      pos 11729
      pos 11798
      pos 11819
      pos 11843
      pos 11863
      pos 11897
      pos 11919
      pos 11943
      pos 11962
      pos 11988
      pos 12033
      pos 12068
      pos 12123
      pos 12162
      pos 12194
      pos 12216
      pos 12227
      pos 12235
      pos 12254
      pos 12299
      pos 12332
      pos 12358
      pos 12383
      pos 12411
      pos 12436
      pos 12474
      pos 12498
      pos 12528
      pos 12572
      pos 12597
      pos 12629
      pos 12670
      pos 12723
      pos 12737
      pos 12746
      pos 12776
      pos 12828
      pos 12900
      pos 12920
      pos 13001
      pos 13072
      pos 13154
      pos 13174
      pos 13256
      pos 13276
      pos 13328
      pos 13407
      pos 13427
      pos 13473
      pos 13493
      pos 13571
      pos 13591
      pos 13663
      pos 13683
      pos 13765
      pos 13785
      pos 13838
      pos 13858
      pos 13910
      pos 13942
      pos 14050
      pos 14070
      pos 14179
      pos 14199
      pos 14248
      pos 14334
    doc 1
      freq 36
      pos 369
      pos 378
      pos 1686
      pos 2323
      pos 2433
      pos 2442
      pos 2490
      pos 2503
      pos 2514
      pos 2742
      pos 2755
      pos 2890
      pos 2982
      pos 3625
      pos 3677
      pos 3682
      pos 3689
      pos 3696
      pos 3711
      pos 3717
      pos 3885
      pos 3889
      pos 3929
      pos 4044
      pos 4399
      pos 4670
      pos 5335
      pos 6068
      pos 6081
      pos 6139
      pos 6219
      pos 7746
      pos 7763
      pos 7778
      pos 7898
      pos 7916
    doc 2
      freq 5
      pos 1648
      pos 1900
      pos 3410
      pos 3437
      pos 6178
    doc 3
      freq 8
      pos 460
      pos 1512
      pos 1529
      pos 1836
      pos 1923
      pos 1938
      pos 2107
      pos 4071
    doc 4
      freq 54
      pos 247
      pos 622
      pos 628
      pos 632
      pos 652
      pos 712
      pos 831
      pos 863
      pos 881
      pos 893
      pos 932
      pos 966
      pos 1279
      pos 1383
      pos 1423
      pos 1436
      pos 1493
      pos 1535
      pos 1577
      pos 1719
      pos 2128
      pos 2165
      pos 2794
      pos 2831
      pos 3039
      pos 3076
      pos 3275
      pos 3312
      pos 3324
      pos 3423
      pos 3477
      pos 3582
      pos 3599
      pos 3753
      pos 3778
      pos 4700
      pos 4749
      pos 4775
      pos 4787
      pos 4794
      pos 4812
      pos 4861
      pos 4935
      pos 4967
      pos 5011
      pos 5048
      pos 5072
      pos 5103
      pos 5126
      pos 5619
      pos 5640
      pos 5714
      pos 5723
      pos 5908
    doc 5
      freq 26
      pos 1613
      pos 1684
      pos 1710
      pos 1773
      pos 1786
      pos 1830
      pos 1833
      pos 1838
      pos 1901
      pos 2036
      pos 2647
      pos 2660
      pos 2665
      pos 2684
      pos 3713
      pos 3719
      pos 3729
      pos 3732
      pos 3835
      pos 3837
      pos 3854
      pos 3861
      pos 3866
      pos 3867
      pos 3883
      pos 3889
    doc 6
      freq 1
      pos 2138
    doc 7
      freq 1
      pos 1948
    doc 8
      freq 40
      pos 128
      pos 135
      pos 145
      pos 152
      pos 162
      pos 426
      pos 483
      pos 493
      pos 495
      pos 501
      pos 513
      pos 533
      pos 553
      pos 583
      pos 620
      pos 627
      pos 810
      pos 826
      pos 1002
      pos 1113
      pos 1139
      pos 1152
      pos 1154
      pos 1160
      pos 1169
      pos 1189
      pos 1295
      pos 1301
      pos 1320
      pos 1333
      pos 1335
      pos 1341
      pos 1350
      pos 1370
      pos 1390
      pos 1490
      pos 1496
      pos 1639
      pos 1648
      pos 1657
    doc 10
      freq 2
      pos 6367
      pos 6667
    doc 11
      freq 30
      pos 439
      pos 853
      pos 1498
      pos 3163
      pos 3395
      pos 3834
      pos 3858
      pos 3868
      pos 4037
      pos 4306
      pos 4484
      pos 4698
      pos 5189
      pos 5346
      pos 5494
      pos 5654
      pos 5974
      pos 6198
      pos 6889
      pos 7223
      pos 7791
      pos 7800
      pos 7841
      pos 7881
      pos 8172
      pos 8353
      pos 8506
      pos 8983
      pos 9105
      pos 9282
    doc 12
      freq 3
      pos 178
      pos 1144
      pos 8182
    doc 13
      freq 2
      pos 2774
      pos 4404
    doc 14
      freq 2
      pos 537
      pos 1832
    doc 16
      freq 5
      pos 1158
      pos 2018
      pos 2029
      pos 2209
      pos 2389
    doc 17
      freq 1
      pos 1797
    doc 18
      freq 2
      pos 735
      pos 798
    skipList 
      level 0
        skipDoc 7
        skipDocFP 2504785
        impacts 
          impact 
            freq 1
            norm 100
          impact 
            freq 26
            norm 104
          impact 
            freq 54
            norm 108
          impact 
            freq 278
            norm 120
        impactsEnd 
        skipDoc 17
        skipDocFP 2511199
        impacts 
          impact 
            freq 40
            norm 97
        impactsEnd 
  term types
    doc 0
      freq 3
      pos 1661
      pos 1723
      pos 6701
    doc 1
      freq 12
      pos 323
      pos 334
      pos 2318
      pos 6193
      pos 6252
      pos 6290
      pos 6328
      pos 6373
      pos 6396
      pos 6468
      pos 7754
      pos 7908
    doc 2
      freq 2
      pos 1585
      pos 3222
    doc 3
      freq 1
      pos 1998
    doc 4
      freq 7
      pos 369
      pos 720
      pos 729
      pos 992
      pos 999
      pos 4823
      pos 5033
    doc 5
      freq 1
      pos 1874
    doc 7
      freq 2
      pos 940
      pos 1557
    doc 8
      freq 8
      pos 282
      pos 359
      pos 824
      pos 833
      pos 844
      pos 864
      pos 884
      pos 1209
    doc 11
      freq 4
      pos 227
      pos 3561
      pos 3573
      pos 4216
    doc 12
      freq 3
      pos 638
      pos 1243
      pos 1702
    doc 13
      freq 3
      pos 508
      pos 940
      pos 968
    doc 14
      freq 1
      pos 1821
    doc 17
      freq 2
      pos 988
      pos 998
    skipList 
      level 0
        skipDoc 8
        skipDocFP 2513195
        impacts 
          impact 
            freq 8
            norm 97
          impact 
            freq 12
            norm 113
        impactsEnd 
  term typical
    doc 6
      freq 3
      pos 1235
      pos 1385
      pos 1438
    doc 9
      freq 2
      pos 611
      pos 1390
    doc 12
      freq 1
      pos 1755
    doc 13
      freq 2
      pos 2601
      pos 3790
    doc 14
      freq 4
      pos 2963
      pos 4154
      pos 4883
      pos 5137
    doc 17
      freq 1
      pos 1143
  term typically
    doc 3
      freq 1
      pos 3159
    doc 6
      freq 2
      pos 1848
      pos 1934
    doc 9
      freq 2
      pos 633
      pos 656
    doc 10
      freq 1
      pos 3833
    doc 12
      freq 17
      pos 1151
      pos 1717
      pos 2217
      pos 2751
      pos 3463
      pos 3801
      pos 3858
      pos 4249
      pos 4505
      pos 4766
      pos 5106
      pos 5496
      pos 5679
      pos 5960
      pos 6016
      pos 6400
      pos 6702
    doc 13
      freq 2
      pos 2579
      pos 4500
    doc 15
      freq 2
      pos 431
      pos 515
  term typos
    doc 4
      freq 1
      pos 5563
  term tzmqnjyktcire29xvm
    doc 11
      freq 1
      pos 10503
  term u
    doc 10
      freq 1
      pos 12641
    doc 11
      freq 3
      pos 3502
      pos 3510
      pos 10368
  term u18z9x
    doc 11
      freq 1
      pos 10230
  term u33jncmzlnt
    doc 11
      freq 1
      pos 10097
  term u46it
    doc 10
      freq 1
      pos 12454
  term u5e0
    doc 10
      freq 1
      pos 6228
  term u5ffdrpqvlyds7ly1ba2k1xbxwtiyl
    doc 11
      freq 1
      pos 9987
  term u8mwxek2qvhoigkicnlrd
    doc 11
      freq 1
      pos 9887
  term u8qpk5uc9wplvfj
    doc 10
      freq 1
      pos 12455
  term u9pm
    doc 10
      freq 1
      pos 12570
  term ua
    doc 10
      freq 3
      pos 1050
      pos 4913
      pos 8565
  term uac
    doc 10
      freq 16
      pos 3225
      pos 4352
      pos 4358
      pos 4409
      pos 4416
      pos 4533
      pos 7557
      pos 7589
      pos 7658
      pos 10240
      pos 10260
      pos 10279
      pos 10298
      pos 12869
      pos 12956
      pos 13054
  term uac's
    doc 10
      freq 1
      pos 10353
  term uacs
    doc 10
      freq 1
      pos 4485
  term uae
    doc 11
      freq 1
      pos 9978
  term uas
    doc 10
      freq 3
      pos 527
      pos 2081
      pos 12893
    doc 11
      freq 1
      pos 9052
  term ubiquitous
    doc 10
      freq 1
      pos 11227
  term uc85
    doc 10
      freq 1
      pos 12459
  term ucqh8c9etumi2uebqhbbdvugnk364c
    doc 10
      freq 1
      pos 6232
  term uct
    doc 11
      freq 1
      pos 6146
  term udp
    doc 4
      freq 1
      pos 2581
    doc 6
      freq 2
      pos 267
      pos 571
    doc 7
      freq 1
      pos 265
    doc 11
      freq 49
      pos 210
      pos 1485
      pos 1518
      pos 2225
      pos 2386
      pos 2702
      pos 3208
      pos 3222
      pos 3356
      pos 3390
      pos 3550
      pos 3606
      pos 3641
      pos 3780
      pos 4012
      pos 4136
      pos 4296
      pos 4371
      pos 4476
      pos 4551
      pos 4689
      pos 5183
      pos 5339
      pos 5484
      pos 5644
      pos 5966
      pos 6180
      pos 6369
      pos 6442
      pos 6604
      pos 6681
      pos 6789
      pos 6884
      pos 6974
      pos 7119
      pos 7218
      pos 7663
      pos 7876
      pos 8134
      pos 8281
      pos 8323
      pos 8474
      pos 8481
      pos 8623
      pos 8732
      pos 8822
      pos 8939
      pos 9097
      pos 9252
    doc 12
      freq 6
      pos 1597
      pos 7614
      pos 8092
      pos 8496
      pos 8710
      pos 9335
  term udt
    doc 11
      freq 1
      pos 9920
  term uffixdzqes1vxspdv9
    doc 10
      freq 1
      pos 12602
  term ufzom9pyfhfvfs9hvjkxs
    doc 10
      freq 1
      pos 12818
  term uid
    doc 16
      freq 16
      pos 1280
      pos 1719
      pos 1784
      pos 1803
      pos 1812
      pos 1831
      pos 2064
      pos 2073
      pos 2098
      pos 2165
      pos 2184
      pos 2193
      pos 2403
      pos 2420
      pos 2439
      pos 2459
  term uidplus
    doc 16
      freq 3
      pos 1188
      pos 1915
      pos 2599
  term uidvalidity
    doc 16
      freq 13
      pos 1782
      pos 1801
      pos 1810
      pos 1829
      pos 2062
      pos 2071
      pos 2163
      pos 2182
      pos 2191
      pos 2401
      pos 2418
      pos 2437
      pos 2457
  term ujiygvd4pwcx
    doc 11
      freq 1
      pos 9948
  term uk
    doc 1
      freq 1
      pos 9553
    doc 3
      freq 1
      pos 5918
  term ulteqj
    doc 11
      freq 1
      pos 10075
  term ultimat
    doc 10
      freq 1
      pos 10316
    doc 12
      freq 2
      pos 6735
      pos 9199
    doc 13
      freq 1
      pos 1002
  term ultimately
    doc 10
      freq 3
      pos 3723
      pos 10002
      pos 11008
  term umxuuwal9lris848gham
    doc 10
      freq 1
      pos 12502
  term unacceptabl
    doc 6
      freq 1
      pos 2425
    doc 11
      freq 2
      pos 516
      pos 8967
  term unaccountabl
    doc 10
      freq 1
      pos 11070
  term unadu
    doc 10
      freq 1
      pos 12656
  term unaltered
    doc 3
      freq 1
      pos 950
  term unambiguously
    doc 11
      freq 1
      pos 791
  term unassigned
    doc 1
      freq 3
      pos 2370
      pos 4549
      pos 7864
    doc 4
      freq 1
      pos 5080
  term unatjmhly6piedtkgzegnabonv97r
    doc 11
      freq 1
      pos 10335
  term unauthenticated
    doc 4
      freq 1
      pos 5848
    doc 10
      freq 1
      pos 11075
  term unauthorized
    doc 1
      freq 2
      pos 8113
      pos 8122
    doc 10
      freq 1
      pos 9401
    doc 12
      freq 1
      pos 5133
    doc 13
      freq 1
      pos 5799
  term unavailability
    doc 4
      freq 1
      pos 1621
  term unavailabl
    doc 10
      freq 1
      pos 11693
    doc 11
      freq 1
      pos 5024
    doc 12
      freq 2
      pos 4027
      pos 4051
    doc 13
      freq 1
      pos 4733
    doc 17
      freq 1
      pos 1628
  term unawar
    doc 12
      freq 1
      pos 2509
  term unb379
    doc 10
      freq 1
      pos 12715
  term uncertain
    doc 12
      freq 1
      pos 6056
  term unchanged
    doc 3
      freq 1
      pos 2727
    doc 10
      freq 1
      pos 3713
    doc 11
      freq 1
      pos 1425
    doc 16
      freq 1
      pos 1100
  term uncontrolled
    doc 4
      freq 1
      pos 870
  term uncovered
    doc 2
      freq 1
      pos 4874
  term uncovering
    doc 2
      freq 1
      pos 2082
  term under
    doc 0
      freq 1
      pos 17377
    doc 1
      freq 1
      pos 9758
    doc 2
      freq 4
      pos 1176
      pos 1344
      pos 6188
      pos 6555
    doc 3
      freq 2
      pos 2170
      pos 6107
    doc 4
      freq 2
      pos 2038
      pos 6262
    doc 5
      freq 1
      pos 4592
    doc 6
      freq 2
      pos 951
      pos 3392
    doc 7
      freq 2
      pos 1326
      pos 3097
    doc 8
      freq 1
      pos 2314
    doc 9
      freq 2
      pos 1228
      pos 1959
    doc 10
      freq 9
      pos 1085
      pos 3432
      pos 3459
      pos 11517
      pos 11620
      pos 11715
      pos 11816
      pos 11910
      pos 13620
    doc 11
      freq 1
      pos 10781
    doc 12
      freq 6
      pos 780
      pos 2327
      pos 2396
      pos 4055
      pos 5080
      pos 9631
    doc 13
      freq 2
      pos 4008
      pos 7246
    doc 14
      freq 1
      pos 5712
    doc 15
      freq 4
      pos 1354
      pos 1366
      pos 1382
      pos 4231
    doc 16
      freq 1
      pos 2842
    doc 17
      freq 2
      pos 1344
      pos 2566
    doc 18
      freq 1
      pos 2354
    skipList 
      level 0
        skipDoc 7
        skipDocFP 2520889
        impacts 
          impact 
            freq 2
            norm 100
          impact 
            freq 4
            norm 108
        impactsEnd 
        skipDoc 15
        skipDocFP 2521298
        impacts 
          impact 
            freq 2
            norm 95
          impact 
            freq 4
            norm 104
          impact 
            freq 6
            norm 113
          impact 
            freq 9
            norm 116
        impactsEnd 
  term underflow
    doc 6
      freq 3
      pos 414
      pos 1655
      pos 2423
  term undergoing
    doc 6
      freq 1
      pos 429
  term underlying
    doc 0
      freq 1
      pos 11994
    doc 3
      freq 1
      pos 1680
    doc 5
      freq 1
      pos 3269
    doc 12
      freq 1
      pos 955
    doc 13
      freq 1
      pos 5096
  term undermin
    doc 17
      freq 1
      pos 1436
  term underscor
    doc 14
      freq 7
      pos 2592
      pos 2642
      pos 2672
      pos 2726
      pos 2760
      pos 2784
      pos 2802
  term understand
    doc 2
      freq 1
      pos 4181
    doc 11
      freq 1
      pos 1884
    doc 12
      freq 2
      pos 2136
      pos 8683
  term understanding
    doc 2
      freq 1
      pos 2122
    doc 13
      freq 1
      pos 2769
    doc 15
      freq 1
      pos 3669
  term understands
    doc 11
      freq 1
      pos 8001
  term undertak
    doc 2
      freq 1
      pos 5171
  term undertaken
    doc 15
      freq 1
      pos 185
  term undesirabl
    doc 11
      freq 1
      pos 9355
  term undesired
    doc 16
      freq 1
      pos 441
  term undue
    doc 2
      freq 1
      pos 5609
  term unescaping
    doc 11
      freq 2
      pos 2097
      pos 2330
  term unet2yxwejrdtn435c0d0yose6zvt7
    doc 11
      freq 1
      pos 9960
  term unexpected
    doc 13
      freq 1
      pos 3087
  term unfavorabl
    doc 11
      freq 1
      pos 707
  term unfolded
    doc 11
      freq 2
      pos 883
      pos 897
  term unfortunately
    doc 2
      freq 1
      pos 4550
    doc 12
      freq 1
      pos 2097
  term ungl9j5j36n87wkjqrbyj
    doc 11
      freq 1
      pos 10124
  term uni
    doc 1
      freq 1
      pos 1665
  term unicast
    doc 4
      freq 7
      pos 1094
      pos 1123
      pos 1166
      pos 1185
      pos 3877
      pos 3927
      pos 5800
    doc 5
      freq 3
      pos 238
      pos 364
      pos 391
    doc 12
      freq 1
      pos 7417
    doc 13
      freq 10
      pos 744
      pos 2364
      pos 2519
      pos 2550
      pos 2591
      pos 3221
      pos 3930
      pos 3939
      pos 4503
      pos 4531
  term unidirectional
    doc 1
      freq 3
      pos 2865
      pos 3369
      pos 3567
    doc 13
      freq 6
      pos 1681
      pos 1972
      pos 2035
      pos 2194
      pos 2315
      pos 3154
  term uniform
    doc 2
      freq 1
      pos 1616
    doc 7
      freq 2
      pos 2611
      pos 2706
    doc 10
      freq 1
      pos 13347
    doc 11
      freq 1
      pos 9683
    doc 13
      freq 1
      pos 5307
  term unimplemented
    doc 12
      freq 1
      pos 1699
  term uninett
    doc 15
      freq 2
      pos 16
      pos 4038
  term uninett.n
    doc 15
      freq 1
      pos 4045
  term unintended
    doc 18
      freq 1
      pos 1683
  term unintentionally
    doc 14
      freq 1
      pos 2312
  term union
    doc 0
      freq 2
      pos 3328
      pos 3363
    doc 15
      freq 1
      pos 919
  term uniqu
    doc 0
      freq 7
      pos 616
      pos 1447
      pos 1559
      pos 6248
      pos 6558
      pos 8935
      pos 10091
    doc 1
      freq 3
      pos 2906
      pos 3179
      pos 3202
    doc 5
      freq 2
      pos 3506
      pos 3530
    doc 10
      freq 4
      pos 9652
      pos 9799
      pos 9810
      pos 9997
    doc 12
      freq 9
      pos 449
      pos 739
      pos 888
      pos 1289
      pos 7414
      pos 7520
      pos 7894
      pos 7900
      pos 7922
    doc 13
      freq 2
      pos 2793
      pos 2830
    doc 15
      freq 2
      pos 2554
      pos 3156
  term uniquely
    doc 0
      freq 2
      pos 5525
      pos 12373
    doc 1
      freq 1
      pos 2937
    doc 4
      freq 1
      pos 1791
    doc 9
      freq 1
      pos 1192
    doc 13
      freq 2
      pos 2355
      pos 5511
  term unit
    doc 1
      freq 2
      pos 453
      pos 6154
    doc 4
      freq 1
      pos 2850
  term united
    doc 15
      freq 1
      pos 4031
  term units
    doc 0
      freq 28
      pos 2544
      pos 2613
      pos 2665
      pos 2808
      pos 2856
      pos 4812
      pos 5022
      pos 6840
      pos 6934
      pos 6981
      pos 7021
      pos 7099
      pos 7156
      pos 7308
      pos 7380
      pos 7413
      pos 7609
      pos 7707
      pos 8039
      pos 8428
      pos 8497
      pos 8555
      pos 8612
      pos 8669
      pos 8714
      pos 8759
      pos 9250
      pos 11922
    doc 1
      freq 1
      pos 132
    doc 2
      freq 1
      pos 3239
    doc 3
      freq 2
      pos 112
      pos 353
  term university
    doc 2
      freq 2
      pos 2865
      pos 5120
    doc 11
      freq 2
      pos 28
      pos 10588
    doc 13
      freq 4
      pos 22
      pos 28
      pos 7042
      pos 7064
    doc 15
      freq 4
      pos 9
      pos 20
      pos 4018
      pos 4049
  term unix
    doc 15
      freq 2
      pos 1055
      pos 3114
  term unknowheaderparam
    doc 11
      freq 1
      pos 2862
  term unknown
    doc 0
      freq 4
      pos 2287
      pos 8762
      pos 8780
      pos 9096
    doc 1
      freq 1
      pos 6124
    doc 4
      freq 4
      pos 1382
      pos 1422
      pos 4432
      pos 4558
    doc 5
      freq 1
      pos 3244
    doc 6
      freq 1
      pos 2255
    doc 10
      freq 3
      pos 4136
      pos 7579
      pos 7655
    doc 11
      freq 35
      pos 225
      pos 360
      pos 373
      pos 410
      pos 423
      pos 437
      pos 442
      pos 1275
      pos 1280
      pos 1285
      pos 1318
      pos 1506
      pos 1634
      pos 1719
      pos 1832
      pos 2449
      pos 2888
      pos 2895
      pos 2902
      pos 2910
      pos 3559
      pos 3665
      pos 6638
      pos 6796
      pos 6806
      pos 7280
      pos 7286
      pos 7471
      pos 7555
      pos 7789
      pos 7799
      pos 7893
      pos 7906
      pos 8780
      pos 8982
    doc 16
      freq 1
      pos 624
    skipList 
      level 0
        skipDoc 16
        skipDocFP 2527537
        impacts 
          impact 
            freq 1
            norm 99
          impact 
            freq 4
            norm 108
          impact 
            freq 35
            norm 114
        impactsEnd 
  term unknownformat
    doc 11
      freq 1
      pos 7883
  term unknownheaderparam
    doc 11
      freq 1
      pos 2856
  term unknownheaderwithunusualvalu
    doc 11
      freq 2
      pos 1360
      pos 1496
  term unknownparam
    doc 11
      freq 7
      pos 1453
      pos 8663
      pos 8686
      pos 8695
      pos 8760
      pos 8795
      pos 8850
  term unknownparam1
    doc 11
      freq 1
      pos 2816
  term unknownvalueless
    doc 11
      freq 1
      pos 2868
  term unknownwith
    doc 11
      freq 1
      pos 1504
  term unkscm
    doc 11
      freq 1
      pos 7376
  term unkscm.nasdfasser0q239nwsdfasdkl34
    doc 11
      freq 1
      pos 7394
  term unksm2
    doc 11
      freq 2
      pos 7635
      pos 7650
  term unless
    doc 0
      freq 1
      pos 1528
    doc 1
      freq 3
      pos 4846
      pos 8155
      pos 8485
    doc 3
      freq 2
      pos 1614
      pos 2846
    doc 9
      freq 1
      pos 1247
    doc 10
      freq 2
      pos 4028
      pos 10971
    doc 11
      freq 1
      pos 6069
    doc 12
      freq 4
      pos 4723
      pos 4747
      pos 4840
      pos 5834
    doc 13
      freq 1
      pos 2551
    doc 14
      freq 2
      pos 640
      pos 1072
    doc 15
      freq 1
      pos 2011
    skipList 
      level 0
        skipDoc 13
        skipDocFP 2529512
        impacts 
          impact 
            freq 1
            norm 95
          impact 
            freq 2
            norm 107
          impact 
            freq 4
            norm 113
        impactsEnd 
  term unlik
    doc 4
      freq 1
      pos 2927
    doc 10
      freq 1
      pos 8186
  term unlikelihood
    doc 12
      freq 1
      pos 5740
  term unlikely
    doc 9
      freq 1
      pos 1487
    doc 10
      freq 1
      pos 3181
  term unlimited
    doc 0
      freq 1
      pos 79
    doc 1
      freq 1
      pos 96
    doc 2
      freq 1
      pos 49
    doc 3
      freq 1
      pos 90
    doc 4
      freq 1
      pos 92
    doc 5
      freq 1
      pos 76
    doc 6
      freq 1
      pos 52
    doc 7
      freq 1
      pos 63
    doc 8
      freq 1
      pos 57
    doc 9
      freq 1
      pos 78
    doc 10
      freq 1
      pos 81
    doc 11
      freq 1
      pos 65
    doc 12
      freq 1
      pos 55
    doc 13
      freq 1
      pos 64
    doc 14
      freq 1
      pos 59
    doc 15
      freq 1
      pos 63
    doc 16
      freq 1
      pos 77
    doc 17
      freq 1
      pos 74
    doc 18
      freq 1
      pos 83
    skipList 
      level 0
        skipDoc 7
        skipDocFP 2530560
        impacts 
          impact 
            freq 1
            norm 100
        impactsEnd 
        skipDoc 15
        skipDocFP 2530848
        impacts 
          impact 
            freq 1
            norm 95
        impactsEnd 
  term unlocks
    doc 10
      freq 1
      pos 2715
  term unmodified
    doc 4
      freq 1
      pos 3955
    doc 5
      freq 1
      pos 3240
    doc 11
      freq 1
      pos 7945
  term unnecessary
    doc 12
      freq 3
      pos 3446
      pos 3513
      pos 3716
    doc 13
      freq 1
      pos 4034
    doc 14
      freq 1
      pos 1238
  term unpadded
    doc 0
      freq 2
      pos 6091
      pos 6121
  term unpopular
    doc 10
      freq 1
      pos 1751
  term unquoted
    doc 11
      freq 1
      pos 6517
  term unreachabl
    doc 4
      freq 15
      pos 188
      pos 765
      pos 2090
      pos 2187
      pos 2190
      pos 2229
      pos 2498
      pos 2565
      pos 2699
      pos 2734
      pos 5075
      pos 5106
      pos 5646
      pos 5712
      pos 5972
    doc 12
      freq 1
      pos 3144
  term unreason
    doc 11
      freq 2
      pos 3993
      pos 4018
  term unreasonably
    doc 11
      freq 1
      pos 4980
  term unrecognized
    doc 1
      freq 3
      pos 2371
      pos 4550
      pos 7865
    doc 4
      freq 4
      pos 1707
      pos 3321
      pos 3327
      pos 3507
    doc 16
      freq 1
      pos 1275
  term unrecoverabl
    doc 12
      freq 2
      pos 8596
      pos 9114
  term unrelated
    doc 6
      freq 1
      pos 2405
    doc 12
      freq 1
      pos 2828
  term unreliability
    doc 12
      freq 1
      pos 3520
  term unreserved
    doc 11
      freq 2
      pos 3947
      pos 3959
  term unscheduled
    doc 13
      freq 1
      pos 3101
  term unsecurabl
    doc 10
      freq 1
      pos 10723
  term unsigned
    doc 3
      freq 1
      pos 3751
    doc 8
      freq 1
      pos 1310
    doc 10
      freq 1
      pos 4655
  term unsigned32
    doc 0
      freq 58
      pos 1026
      pos 1630
      pos 1742
      pos 1793
      pos 1825
      pos 2017
      pos 2030
      pos 2052
      pos 2065
      pos 2087
      pos 2466
      pos 2529
      pos 4521
      pos 4612
      pos 4725
      pos 5021
      pos 5500
      pos 5508
      pos 6020
      pos 6214
      pos 6359
      pos 6365
      pos 6367
      pos 6369
      pos 6373
      pos 6375
      pos 6377
      pos 6501
      pos 6780
      pos 6837
      pos 6931
      pos 7018
      pos 7096
      pos 7153
      pos 7807
      pos 7930
      pos 8887
      pos 8899
      pos 8912
      pos 9147
      pos 9490
      pos 9497
      pos 9673
      pos 9682
      pos 10035
      pos 10072
      pos 11047
      pos 11246
      pos 11785
      pos 11845
      pos 12109
      pos 12111
      pos 12125
      pos 12164
      pos 12334
      pos 12500
      pos 12672
      pos 12725
  term unsolicited
    doc 1
      freq 2
      pos 1848
      pos 2062
  term unspecified
    doc 4
      freq 1
      pos 1799
    doc 12
      freq 4
      pos 3065
      pos 3158
      pos 4551
      pos 5672
    doc 14
      freq 1
      pos 585
  term unsuccessful
    doc 12
      freq 1
      pos 2705
  term unsupported
    doc 10
      freq 5
      pos 332
      pos 4148
      pos 11680
      pos 11733
      pos 11829
    doc 11
      freq 4
      pos 7315
      pos 7476
      pos 7705
      pos 7839
  term unswitched
    doc 1
      freq 1
      pos 1915
  term unsynchronized
    doc 13
      freq 2
      pos 4763
      pos 4783
  term untagged
    doc 3
      freq 1
      pos 1526
  term unterminated
    doc 11
      freq 3
      pos 283
      pos 5077
      pos 5089
  term until
    doc 0
      freq 1
      pos 5024
    doc 1
      freq 3
      pos 1538
      pos 7424
      pos 7589
    doc 2
      freq 3
      pos 3893
      pos 4402
      pos 4546
    doc 3
      freq 1
      pos 5355
    doc 6
      freq 1
      pos 2582
    doc 12
      freq 2
      pos 2537
      pos 3482
    doc 14
      freq 4
      pos 730
      pos 894
      pos 1414
      pos 1591
    doc 15
      freq 2
      pos 1371
      pos 3338
    skipList 
      level 0
        skipDoc 15
        skipDocFP 2535009
        impacts 
          impact 
            freq 1
            norm 101
          impact 
            freq 2
            norm 104
          impact 
            freq 4
            norm 107
        impactsEnd 
  term untimely
    doc 17
      freq 1
      pos 1626
  term untrusted
    doc 10
      freq 2
      pos 4129
      pos 4134
  term unused
    doc 1
      freq 1
      pos 3810
    doc 4
      freq 6
      pos 2131
      pos 2203
      pos 2207
      pos 3042
      pos 3090
      pos 3094
  term unusual
    doc 10
      freq 1
      pos 5894
    doc 11
      freq 7
      pos 235
      pos 687
      pos 1306
      pos 1311
      pos 1651
      pos 1853
      pos 3916
  term unusually
    doc 4
      freq 1
      pos 1563
  term unwanted
    doc 1
      freq 1
      pos 8104
    doc 9
      freq 1
      pos 1509
    doc 13
      freq 1
      pos 4581
  term unwary
    doc 11
      freq 1
      pos 2434
  term unwilling
    doc 10
      freq 1
      pos 10732
  term uohvntw4ldzrpf9
    doc 11
      freq 1
      pos 10405
  term up
    doc 0
      freq 10
      pos 926
      pos 6804
      pos 8973
      pos 9000
      pos 9337
      pos 9364
      pos 12395
      pos 12648
      pos 14006
      pos 14220
    doc 1
      freq 17
      pos 745
      pos 947
      pos 1836
      pos 1907
      pos 2156
      pos 2204
      pos 2255
      pos 2814
      pos 3083
      pos 3226
      pos 4431
      pos 4717
      pos 5614
      pos 6309
      pos 7941
      pos 7949
      pos 8437
    doc 2
      freq 1
      pos 4457
    doc 3
      freq 5
      pos 393
      pos 1097
      pos 2231
      pos 2245
      pos 5390
    doc 4
      freq 1
      pos 1922
    doc 5
      freq 4
      pos 1768
      pos 2919
      pos 3779
      pos 3995
    doc 6
      freq 1
      pos 1446
    doc 7
      freq 1
      pos 414
    doc 8
      freq 14
      pos 487
      pos 815
      pos 922
      pos 945
      pos 954
      pos 962
      pos 966
      pos 1029
      pos 1144
      pos 1247
      pos 1325
      pos 1428
      pos 1515
      pos 1569
    doc 12
      freq 23
      pos 1469
      pos 1751
      pos 2176
      pos 2682
      pos 3265
      pos 3308
      pos 3453
      pos 4614
      pos 4733
      pos 4969
      pos 5061
      pos 5550
      pos 5669
      pos 5710
      pos 5815
      pos 6429
      pos 6450
      pos 6480
      pos 6594
      pos 6906
      pos 8254
      pos 9234
      pos 9339
    doc 13
      freq 12
      pos 184
      pos 467
      pos 1632
      pos 2431
      pos 2435
      pos 2535
      pos 4004
      pos 4108
      pos 4133
      pos 4143
      pos 4798
      pos 6427
    doc 15
      freq 2
      pos 336
      pos 2218
    skipList 
      level 0
        skipDoc 7
        skipDocFP 2536574
        impacts 
          impact 
            freq 1
            norm 100
          impact 
            freq 4
            norm 104
          impact 
            freq 5
            norm 107
          impact 
            freq 17
            norm 113
        impactsEnd 
  term upblo7vfyquls7mp587cp8qzhdmffoxr9x790am
    doc 11
      freq 1
      pos 10080
  term upd
    doc 10
      freq 2
      pos 5805
      pos 5836
  term updat
    doc 0
      freq 1
      pos 16507
    doc 4
      freq 1
      pos 4921
    doc 7
      freq 2
      pos 1422
      pos 1524
    doc 9
      freq 14
      pos 507
      pos 706
      pos 820
      pos 841
      pos 872
      pos 914
      pos 946
      pos 1144
      pos 1162
      pos 1188
      pos 1283
      pos 1294
      pos 1332
      pos 1459
    doc 12
      freq 13
      pos 4296
      pos 4704
      pos 5470
      pos 5503
      pos 5528
      pos 5532
      pos 5539
      pos 5694
      pos 5785
      pos 5798
      pos 6019
      pos 7029
      pos 7118
    doc 13
      freq 4
      pos 1779
      pos 1844
      pos 3361
      pos 4127
  term updated
    doc 0
      freq 1
      pos 1073
    doc 2
      freq 2
      pos 3714
      pos 3956
    doc 4
      freq 3
      pos 5058
      pos 5947
      pos 5956
    doc 6
      freq 2
      pos 1040
      pos 1399
    doc 12
      freq 7
      pos 1350
      pos 5192
      pos 5270
      pos 5515
      pos 5829
      pos 6176
      pos 6408
    doc 13
      freq 6
      pos 802
      pos 2859
      pos 5514
      pos 5604
      pos 5619
      pos 6505
    doc 16
      freq 1
      pos 2050
  term updater
    doc 12
      freq 3
      pos 4265
      pos 4620
      pos 5566
  term updates
    doc 0
      freq 3
      pos 16236
      pos 16546
      pos 16569
    doc 1
      freq 1
      pos 5956
    doc 2
      freq 1
      pos 4980
    doc 4
      freq 3
      pos 14
      pos 437
      pos 5899
    doc 9
      freq 1
      pos 113
    doc 12
      freq 27
      pos 112
      pos 363
      pos 387
      pos 707
      pos 4252
      pos 4310
      pos 4376
      pos 4412
      pos 4463
      pos 4580
      pos 4608
      pos 4674
      pos 5263
      pos 5406
      pos 5444
      pos 5559
      pos 5603
      pos 5654
      pos 6083
      pos 6101
      pos 6129
      pos 6141
      pos 6189
      pos 6398
      pos 6458
      pos 6865
      pos 7022
    doc 13
      freq 3
      pos 1695
      pos 4248
      pos 4761
    doc 14
      freq 1
      pos 2479
    doc 16
      freq 1
      pos 11
    doc 18
      freq 1
      pos 11
    skipList 
      level 0
        skipDoc 14
        skipDocFP 2539987
        impacts 
          impact 
            freq 1
            norm 95
          impact 
            freq 3
            norm 108
          impact 
            freq 27
            norm 113
        impactsEnd 
  term updating
    doc 12
      freq 13
      pos 356
      pos 374
      pos 4208
      pos 4216
      pos 4322
      pos 4422
      pos 4722
      pos 4782
      pos 4923
      pos 4924
      pos 5393
      pos 5997
      pos 6040
    doc 13
      freq 3
      pos 86
      pos 666
      pos 4810
  term updmzjcd2w5q4tnrblsmy4waao7eogbkzso6cb4d5mihliqzkdjkxfkzmxwj
    doc 10
      freq 1
      pos 12616
  term upgraded
    doc 12
      freq 1
      pos 3320
  term upload
    doc 16
      freq 4
      pos 156
      pos 352
      pos 401
      pos 1769
  term upon
    doc 0
      freq 2
      pos 1469
      pos 16356
    doc 1
      freq 2
      pos 2724
      pos 4189
    doc 2
      freq 2
      pos 887
      pos 1693
    doc 3
      freq 1
      pos 3715
    doc 4
      freq 1
      pos 4622
    doc 5
      freq 2
      pos 2320
      pos 2414
    doc 9
      freq 1
      pos 830
    doc 13
      freq 1
      pos 4584
    doc 15
      freq 2
      pos 2210
      pos 3593
    doc 16
      freq 1
      pos 2234
    skipList 
      level 0
        skipDoc 13
        skipDocFP 2541698
        impacts 
          impact 
            freq 1
            norm 95
          impact 
            freq 2
            norm 104
        impactsEnd 
  term upper
    doc 4
      freq 22
      pos 1048
      pos 1395
      pos 1486
      pos 1490
      pos 1515
      pos 1532
      pos 1574
      pos 2725
      pos 2739
      pos 2971
      pos 2985
      pos 3208
      pos 3221
      pos 3512
      pos 3524
      pos 3699
      pos 3962
      pos 4574
      pos 4585
      pos 4599
      pos 4632
      pos 4645
    doc 6
      freq 1
      pos 369
    doc 9
      freq 1
      pos 1573
    doc 14
      freq 2
      pos 1888
      pos 2619
  term uppercas
    doc 14
      freq 15
      pos 625
      pos 830
      pos 1032
      pos 1523
      pos 1684
      pos 1917
      pos 1937
      pos 1971
      pos 1978
      pos 1994
      pos 2000
      pos 2066
      pos 2925
      pos 3568
      pos 4536
  term ups
    doc 7
      freq 1
      pos 2548
  term upset
    doc 6
      freq 1
      pos 2398
    doc 10
      freq 1
      pos 3183
  term upstream
    doc 6
      freq 1
      pos 2281
  term uri
    doc 10
      freq 51
      pos 260
      pos 438
      pos 927
      pos 1039
      pos 1046
      pos 2387
      pos 2442
      pos 2920
      pos 3027
      pos 3345
      pos 3405
      pos 3415
      pos 3436
      pos 3448
      pos 3463
      pos 3526
      pos 3588
      pos 3990
      pos 4045
      pos 4172
      pos 4450
      pos 4463
      pos 4491
      pos 5577
      pos 5661
      pos 7395
      pos 7446
      pos 7462
      pos 7487
      pos 7506
      pos 7535
      pos 7546
      pos 7566
      pos 7615
      pos 7621
      pos 7701
      pos 8252
      pos 8365
      pos 8445
      pos 8791
      pos 9804
      pos 10387
      pos 10623
      pos 10663
      pos 11667
      pos 11677
      pos 11690
      pos 11764
      pos 13317
      pos 13350
      pos 13426
    doc 11
      freq 52
      pos 218
      pos 293
      pos 299
      pos 326
      pos 342
      pos 408
      pos 415
      pos 424
      pos 1277
      pos 1327
      pos 1649
      pos 1854
      pos 2033
      pos 2069
      pos 2075
      pos 2081
      pos 2098
      pos 2185
      pos 2187
      pos 2523
      pos 2746
      pos 3454
      pos 3472
      pos 3491
      pos 5246
      pos 5255
      pos 5404
      pos 5415
      pos 5846
      pos 5855
      pos 5905
      pos 6258
      pos 6267
      pos 6291
      pos 7278
      pos 7287
      pos 7292
      pos 7316
      pos 7357
      pos 7411
      pos 7422
      pos 7463
      pos 7477
      pos 7556
      pos 7603
      pos 7629
      pos 8777
      pos 8882
      pos 8907
      pos 9686
      pos 10582
      pos 10610
    doc 13
      freq 1
      pos 1307
    doc 16
      freq 1
      pos 2672
    doc 17
      freq 1
      pos 1036
  term uris
    doc 10
      freq 15
      pos 1199
      pos 1205
      pos 2863
      pos 2934
      pos 4476
      pos 5603
      pos 5613
      pos 5625
      pos 5691
      pos 5704
      pos 7647
      pos 7832
      pos 7858
      pos 7867
      pos 7924
    doc 11
      freq 8
      pos 161
      pos 2059
      pos 2302
      pos 2308
      pos 2353
      pos 7435
      pos 7486
      pos 7499
  term urkl
    doc 11
      freq 1
      pos 9926
  term url
    doc 7
      freq 1
      pos 2614
    doc 10
      freq 3
      pos 6588
      pos 6729
      pos 7304
    doc 11
      freq 9
      pos 504
      pos 511
      pos 8675
      pos 8689
      pos 8701
      pos 8767
      pos 8798
      pos 8809
      pos 8871
    doc 16
      freq 38
      pos 265
      pos 589
      pos 761
      pos 766
      pos 777
      pos 833
      pos 837
      pos 902
      pos 919
      pos 953
      pos 1008
      pos 1011
      pos 1093
      pos 1273
      pos 1276
      pos 1292
      pos 1487
      pos 1493
      pos 1494
      pos 1515
      pos 1518
      pos 1542
      pos 1545
      pos 1635
      pos 1780
      pos 1799
      pos 1808
      pos 1827
      pos 2060
      pos 2069
      pos 2161
      pos 2180
      pos 2189
      pos 2399
      pos 2416
      pos 2435
      pos 2504
      pos 2539
  term urls
    doc 16
      freq 10
      pos 259
      pos 731
      pos 860
      pos 890
      pos 995
      pos 1266
      pos 1351
      pos 1623
      pos 2281
      pos 2478
  term us
    doc 10
      freq 1
      pos 13417
    doc 11
      freq 1
      pos 10601
    doc 12
      freq 1
      pos 3441
    doc 14
      freq 15
      pos 626
      pos 831
      pos 1033
      pos 1524
      pos 1685
      pos 1918
      pos 1928
      pos 1935
      pos 2067
      pos 2194
      pos 2204
      pos 2254
      pos 2926
      pos 3566
      pos 4534
    doc 16
      freq 5
      pos 2000
      pos 2033
      pos 2213
      pos 2368
      pos 2663
    doc 18
      freq 1
      pos 2170
  term usa
    doc 2
      freq 1
      pos 6385
    doc 3
      freq 1
      pos 4911
    doc 4
      freq 2
      pos 6054
      pos 6072
    doc 9
      freq 1
      pos 1777
    doc 10
      freq 1
      pos 13445
    doc 12
      freq 1
      pos 9437
    doc 13
      freq 1
      pos 7072
  term usa.telekom.d
    doc 3
      freq 1
      pos 4914
  term usage
    doc 0
      freq 1
      pos 9205
    doc 1
      freq 2
      pos 5622
      pos 5927
    doc 2
      freq 6
      pos 282
      pos 3179
      pos 4882
      pos 5091
      pos 5291
      pos 5950
    doc 4
      freq 1
      pos 871
    doc 5
      freq 2
      pos 961
      pos 2198
    doc 10
      freq 4
      pos 714
      pos 5559
      pos 7921
      pos 10901
    doc 12
      freq 3
      pos 792
      pos 5048
      pos 5909
    doc 13
      freq 7
      pos 1549
      pos 2726
      pos 2777
      pos 3884
      pos 3900
      pos 5081
      pos 6870
    skipList 
      level 0
        skipDoc 13
        skipDocFP 2547438
        impacts 
          impact 
            freq 2
            norm 104
          impact 
            freq 6
            norm 108
          impact 
            freq 7
            norm 109
        impactsEnd 
  term use
    doc 0
      freq 17
      pos 101
      pos 1860
      pos 3538
      pos 3551
      pos 5289
      pos 10727
      pos 10737
      pos 16363
      pos 16384
      pos 16449
      pos 16583
      pos 16898
      pos 16947
      pos 16963
      pos 17310
      pos 17362
      pos 17456
    doc 1
      freq 30
      pos 144
      pos 294
      pos 731
      pos 896
      pos 1956
      pos 3105
      pos 4166
      pos 4251
      pos 4808
      pos 4922
      pos 5031
      pos 5371
      pos 6420
      pos 6488
      pos 6570
      pos 6610
      pos 6675
      pos 6711
      pos 6740
      pos 7001
      pos 7020
      pos 7045
      pos 7060
      pos 7419
      pos 8413
      pos 8667
      pos 8900
      pos 9691
      pos 9743
      pos 9837
    doc 2
      freq 11
      pos 580
      pos 876
      pos 1573
      pos 2400
      pos 3415
      pos 6156
      pos 6294
      pos 6317
      pos 6488
      pos 6540
      pos 6634
    doc 3
      freq 10
      pos 2970
      pos 3702
      pos 4151
      pos 4327
      pos 4498
      pos 5254
      pos 5266
      pos 6040
      pos 6092
      pos 6186
    doc 4
      freq 6
      pos 849
      pos 5273
      pos 5830
      pos 6195
      pos 6247
      pos 6341
    doc 5
      freq 11
      pos 151
      pos 1169
      pos 2223
      pos 2879
      pos 3815
      pos 4031
      pos 4128
      pos 4217
      pos 4525
      pos 4577
      pos 4671
    doc 6
      freq 7
      pos 779
      pos 833
      pos 1971
      pos 2013
      pos 3325
      pos 3377
      pos 3471
    doc 7
      freq 9
      pos 671
      pos 961
      pos 1230
      pos 1314
      pos 1970
      pos 2405
      pos 3030
      pos 3082
      pos 3176
    doc 8
      freq 5
      pos 1768
      pos 2118
      pos 2247
      pos 2299
      pos 2393
    doc 9
      freq 15
      pos 194
      pos 282
      pos 319
      pos 733
      pos 744
      pos 1019
      pos 1150
      pos 1241
      pos 1409
      pos 1525
      pos 1541
      pos 1671
      pos 1892
      pos 1944
      pos 2038
    doc 10
      freq 36
      pos 316
      pos 1321
      pos 1458
      pos 1758
      pos 1903
      pos 2722
      pos 2805
      pos 3890
      pos 4470
      pos 4488
      pos 5153
      pos 5598
      pos 5905
      pos 5951
      pos 6065
      pos 6079
      pos 6111
      pos 6160
      pos 7951
      pos 8124
      pos 8457
      pos 8575
      pos 9065
      pos 10300
      pos 10770
      pos 11302
      pos 11343
      pos 11550
      pos 11633
      pos 12394
      pos 12398
      pos 13047
      pos 13122
      pos 13553
      pos 13605
      pos 13699
    doc 11
      freq 12
      pos 151
      pos 164
      pos 597
      pos 2004
      pos 2405
      pos 6103
      pos 9346
      pos 9799
      pos 9803
      pos 10714
      pos 10766
      pos 10860
    doc 12
      freq 36
      pos 254
      pos 287
      pos 425
      pos 660
      pos 807
      pos 852
      pos 1266
      pos 1336
      pos 1929
      pos 1987
      pos 2116
      pos 2185
      pos 2263
      pos 2491
      pos 2793
      pos 3682
      pos 3704
      pos 4061
      pos 4067
      pos 4787
      pos 4963
      pos 5021
      pos 5203
      pos 5221
      pos 5296
      pos 6343
      pos 6560
      pos 6572
      pos 6797
      pos 6964
      pos 7848
      pos 7947
      pos 8717
      pos 9564
      pos 9616
      pos 9710
    doc 13
      freq 25
      pos 161
      pos 169
      pos 199
      pos 890
      pos 1086
      pos 1231
      pos 2002
      pos 2009
      pos 2068
      pos 2360
      pos 2381
      pos 2731
      pos 2744
      pos 2882
      pos 3275
      pos 3412
      pos 3906
      pos 3994
      pos 4210
      pos 5372
      pos 5545
      pos 6741
      pos 7179
      pos 7231
      pos 7325
    doc 14
      freq 10
      pos 203
      pos 487
      pos 1125
      pos 1850
      pos 2502
      pos 2539
      pos 2574
      pos 5645
      pos 5697
      pos 5791
    doc 15
      freq 18
      pos 406
      pos 722
      pos 734
      pos 756
      pos 798
      pos 907
      pos 954
      pos 1000
      pos 1062
      pos 1172
      pos 1568
      pos 2196
      pos 2277
      pos 2571
      pos 2606
      pos 4164
      pos 4216
      pos 4310
    doc 16
      freq 6
      pos 312
      pos 1003
      pos 1620
      pos 2775
      pos 2827
      pos 2921
    doc 17
      freq 9
      pos 737
      pos 750
      pos 990
      pos 1711
      pos 1755
      pos 2033
      pos 2499
      pos 2551
      pos 2645
    doc 18
      freq 10
      pos 359
      pos 430
      pos 486
      pos 1594
      pos 1740
      pos 1885
      pos 2132
      pos 2287
      pos 2339
      pos 2433
    skipList 
      level 0
        skipDoc 7
        skipDocFP 2548306
        impacts 
          impact 
            freq 9
            norm 100
          impact 
            freq 11
            norm 104
          impact 
            freq 30
            norm 113
        impactsEnd 
        skipDoc 15
        skipDocFP 2550009
        impacts 
          impact 
            freq 15
            norm 95
          impact 
            freq 18
            norm 104
          impact 
            freq 25
            norm 109
          impact 
            freq 36
            norm 113
        impactsEnd 
  term used
    doc 0
      freq 47
      pos 130
      pos 328
      pos 505
      pos 612
      pos 1143
      pos 1588
      pos 1731
      pos 2628
      pos 3509
      pos 5252
      pos 5422
      pos 5523
      pos 5857
      pos 6226
      pos 6239
      pos 6289
      pos 6531
      pos 6565
      pos 6574
      pos 6806
      pos 6816
      pos 6869
      pos 7787
      pos 9189
      pos 10265
      pos 10321
      pos 10343
      pos 10360
      pos 11260
      pos 15466
      pos 15534
      pos 15580
      pos 15613
      pos 15685
      pos 15713
      pos 15755
      pos 15785
      pos 15999
      pos 16007
      pos 16190
      pos 16253
      pos 16281
      pos 16334
      pos 16496
      pos 16551
      pos 16622
      pos 16667
    doc 1
      freq 53
      pos 911
      pos 1393
      pos 1844
      pos 1857
      pos 1886
      pos 1945
      pos 1996
      pos 2109
      pos 2126
      pos 2150
      pos 2167
      pos 2172
      pos 2265
      pos 2285
      pos 2397
      pos 2540
      pos 2641
      pos 2656
      pos 2772
      pos 2823
      pos 2845
      pos 2903
      pos 3080
      pos 3628
      pos 3722
      pos 3953
      pos 3971
      pos 4138
      pos 4151
      pos 4273
      pos 5458
      pos 5467
      pos 5502
      pos 5534
      pos 5667
      pos 5902
      pos 5982
      pos 6228
      pos 6550
      pos 6590
      pos 6816
      pos 6823
      pos 6922
      pos 7013
      pos 7039
      pos 7113
      pos 7122
      pos 7158
      pos 7210
      pos 8036
      pos 8434
      pos 8649
      pos 8758
    doc 2
      freq 4
      pos 1014
      pos 3947
      pos 4158
      pos 5784
    doc 3
      freq 17
      pos 105
      pos 488
      pos 1464
      pos 1619
      pos 1951
      pos 2033
      pos 2179
      pos 2228
      pos 2377
      pos 2701
      pos 2736
      pos 3728
      pos 3760
      pos 3771
      pos 4215
      pos 4244
      pos 4259
    doc 4
      freq 13
      pos 113
      pos 332
      pos 478
      pos 572
      pos 655
      pos 668
      pos 942
      pos 1203
      pos 1301
      pos 1510
      pos 2894
      pos 3181
      pos 4356
    doc 5
      freq 21
      pos 435
      pos 609
      pos 648
      pos 856
      pos 1017
      pos 1298
      pos 1403
      pos 1667
      pos 1900
      pos 2057
      pos 2069
      pos 2533
      pos 2595
      pos 2910
      pos 2950
      pos 3586
      pos 3615
      pos 3931
      pos 3944
      pos 3956
      pos 3967
    doc 6
      freq 10
      pos 188
      pos 257
      pos 534
      pos 989
      pos 1701
      pos 1820
      pos 1887
      pos 1935
      pos 2493
      pos 2623
    doc 7
      freq 2
      pos 490
      pos 1206
    doc 8
      freq 3
      pos 355
      pos 375
      pos 1689
    doc 9
      freq 9
      pos 109
      pos 376
      pos 502
      pos 698
      pos 720
      pos 853
      pos 1091
      pos 1098
      pos 1139
    doc 10
      freq 21
      pos 148
      pos 936
      pos 1040
      pos 2420
      pos 3074
      pos 3547
      pos 4004
      pos 4303
      pos 5112
      pos 5544
      pos 7412
      pos 8274
      pos 10237
      pos 10607
      pos 10833
      pos 11048
      pos 11659
      pos 11753
      pos 11866
      pos 11960
      pos 12043
    doc 11
      freq 2
      pos 4639
      pos 9374
    doc 12
      freq 18
      pos 907
      pos 957
      pos 985
      pos 1053
      pos 1073
      pos 1153
      pos 2103
      pos 2370
      pos 2811
      pos 4460
      pos 4538
      pos 5521
      pos 5600
      pos 5732
      pos 5896
      pos 6063
      pos 6174
      pos 9149
    doc 13
      freq 19
      pos 394
      pos 616
      pos 1224
      pos 1288
      pos 1411
      pos 1716
      pos 1838
      pos 2611
      pos 3034
      pos 3146
      pos 3159
      pos 3186
      pos 3342
      pos 3457
      pos 3493
      pos 4607
      pos 5080
      pos 5357
      pos 5657
    doc 14
      freq 9
      pos 90
      pos 552
      pos 575
      pos 1811
      pos 2019
      pos 2517
      pos 2712
      pos 2770
      pos 2858
    doc 15
      freq 10
      pos 432
      pos 991
      pos 1182
      pos 1264
      pos 1415
      pos 1451
      pos 2086
      pos 2214
      pos 2241
      pos 2371
    doc 16
      freq 9
      pos 424
      pos 477
      pos 694
      pos 720
      pos 899
      pos 1215
      pos 1874
      pos 2132
      pos 2294
    doc 17
      freq 10
      pos 262
      pos 392
      pos 488
      pos 582
      pos 683
      pos 957
      pos 1076
      pos 1113
      pos 1656
      pos 1873
    doc 18
      freq 4
      pos 943
      pos 1073
      pos 1084
      pos 1100
    skipList 
      level 0
        skipDoc 7
        skipDocFP 2553604
        impacts 
          impact 
            freq 2
            norm 100
          impact 
            freq 10
            norm 101
          impact 
            freq 21
            norm 104
          impact 
            freq 53
            norm 113
        impactsEnd 
        skipDoc 15
        skipDocFP 2556299
        impacts 
          impact 
            freq 9
            norm 95
          impact 
            freq 10
            norm 104
          impact 
            freq 19
            norm 109
          impact 
            freq 21
            norm 116
        impactsEnd 
  term useful
    doc 0
      freq 1
      pos 13066
    doc 1
      freq 1
      pos 2707
    doc 2
      freq 3
      pos 1534
      pos 1601
      pos 2080
    doc 5
      freq 1
      pos 3248
    doc 9
      freq 4
      pos 98
      pos 388
      pos 536
      pos 686
    doc 12
      freq 7
      pos 2968
      pos 3359
      pos 5047
      pos 5386
      pos 6774
      pos 6817
      pos 9257
    doc 13
      freq 2
      pos 3230
      pos 4501
    doc 18
      freq 1
      pos 422
    skipList 
      level 0
        skipDoc 18
        skipDocFP 2558926
        impacts 
          impact 
            freq 4
            norm 95
          impact 
            freq 7
            norm 113
        impactsEnd 
  term usefulness
    doc 9
      freq 1
      pos 1602
  term useless
    doc 7
      freq 1
      pos 1772
    doc 12
      freq 1
      pos 3672
  term user
    doc 2
      freq 4
      pos 3030
      pos 3129
      pos 3146
      pos 3176
    doc 3
      freq 3
      pos 3791
      pos 5467
      pos 5678
    doc 6
      freq 2
      pos 2683
      pos 2785
    doc 7
      freq 1
      pos 1887
    doc 9
      freq 1
      pos 1249
    doc 10
      freq 81
      pos 215
      pos 450
      pos 466
      pos 475
      pos 525
      pos 548
      pos 554
      pos 589
      pos 848
      pos 883
      pos 906
      pos 949
      pos 959
      pos 973
      pos 985
      pos 1000
      pos 1183
      pos 1214
      pos 1315
      pos 1357
      pos 1543
      pos 1608
      pos 1656
      pos 1688
      pos 1715
      pos 2057
      pos 2061
      pos 2078
      pos 2124
      pos 2678
      pos 2681
      pos 2689
      pos 2695
      pos 2699
      pos 2817
      pos 2825
      pos 2991
      pos 2995
      pos 3222
      pos 3423
      pos 3425
      pos 3520
      pos 3739
      pos 3885
      pos 4312
      pos 4331
      pos 4514
      pos 4621
      pos 4633
      pos 4643
      pos 4644
      pos 4665
      pos 6288
      pos 7451
      pos 7808
      pos 7935
      pos 8377
      pos 8394
      pos 8428
      pos 8439
      pos 8722
      pos 8782
      pos 8971
      pos 9109
      pos 9352
      pos 9390
      pos 9402
      pos 9568
      pos 9597
      pos 9686
      pos 9979
      pos 10026
      pos 10051
      pos 10074
      pos 10498
      pos 10863
      pos 11210
      pos 12895
      pos 12914
      pos 12923
      pos 13033
    doc 11
      freq 12
      pos 219
      pos 2804
      pos 3455
      pos 3467
      pos 3497
      pos 3500
      pos 3848
      pos 5143
      pos 5159
      pos 9050
      pos 9258
      pos 9272
    doc 12
      freq 5
      pos 2374
      pos 5114
      pos 5624
      pos 6977
      pos 9200
    doc 13
      freq 24
      pos 787
      pos 888
      pos 1003
      pos 2478
      pos 2539
      pos 2543
      pos 2589
      pos 2605
      pos 2976
      pos 2989
      pos 3134
      pos 3273
      pos 3509
      pos 3543
      pos 3574
      pos 3583
      pos 4429
      pos 4921
      pos 4923
      pos 5771
      pos 6042
      pos 6065
      pos 6158
      pos 6207
    doc 16
      freq 5
      pos 923
      pos 926
      pos 929
      pos 935
      pos 957
    doc 17
      freq 7
      pos 396
      pos 924
      pos 1006
      pos 1061
      pos 1084
      pos 1091
      pos 2354
    skipList 
      level 0
        skipDoc 12
        skipDocFP 2559793
        impacts 
          impact 
            freq 1
            norm 95
          impact 
            freq 2
            norm 101
          impact 
            freq 3
            norm 107
          impact 
            freq 4
            norm 108
          impact 
            freq 5
            norm 113
          impact 
            freq 12
            norm 114
          impact 
            freq 81
            norm 116
        impactsEnd 
  term user's
    doc 3
      freq 2
      pos 5228
      pos 5670
    doc 10
      freq 3
      pos 1274
      pos 10747
      pos 10811
    doc 12
      freq 1
      pos 5001
    doc 13
      freq 2
      pos 3287
      pos 3604
  term usera
    doc 10
      freq 3
      pos 6376
      pos 6501
      pos 6676
  term usernam
    doc 2
      freq 4
      pos 575
      pos 900
      pos 967
      pos 4085
    doc 7
      freq 1
      pos 2799
    doc 10
      freq 12
      pos 2726
      pos 2763
      pos 2767
      pos 2779
      pos 2806
      pos 2850
      pos 2871
      pos 2875
      pos 2938
      pos 7441
      pos 7454
      pos 7618
    doc 11
      freq 1
      pos 2346
  term usernotic
    doc 17
      freq 5
      pos 928
      pos 929
      pos 2207
      pos 2358
      pos 2359
  term userpart
    doc 11
      freq 2
      pos 2040
      pos 2313
  term userparts
    doc 11
      freq 1
      pos 2065
  term users
    doc 0
      freq 2
      pos 16868
      pos 17464
    doc 1
      freq 1
      pos 9845
    doc 2
      freq 1
      pos 6642
    doc 3
      freq 1
      pos 6194
    doc 4
      freq 1
      pos 6349
    doc 5
      freq 1
      pos 4679
    doc 6
      freq 1
      pos 3479
    doc 7
      freq 1
      pos 3184
    doc 8
      freq 1
      pos 2401
    doc 9
      freq 4
      pos 458
      pos 578
      pos 626
      pos 2046
    doc 10
      freq 18
      pos 111
      pos 1467
      pos 1634
      pos 1678
      pos 1753
      pos 2157
      pos 2201
      pos 9199
      pos 9305
      pos 9657
      pos 9824
      pos 9830
      pos 9917
      pos 10580
      pos 11055
      pos 11069
      pos 11079
      pos 13707
    doc 11
      freq 1
      pos 10868
    doc 12
      freq 5
      pos 2360
      pos 2508
      pos 5134
      pos 9315
      pos 9718
    doc 13
      freq 15
      pos 2529
      pos 2620
      pos 2635
      pos 2706
      pos 3042
      pos 3271
      pos 3377
      pos 4930
      pos 5722
      pos 5761
      pos 6031
      pos 6101
      pos 6105
      pos 6223
      pos 7333
    doc 14
      freq 1
      pos 5799
    doc 15
      freq 1
      pos 4318
    doc 16
      freq 1
      pos 2929
    doc 17
      freq 1
      pos 2653
    doc 18
      freq 1
      pos 2441
    skipList 
      level 0
        skipDoc 7
        skipDocFP 2563675
        impacts 
          impact 
            freq 1
            norm 100
          impact 
            freq 2
            norm 120
        impactsEnd 
        skipDoc 15
        skipDocFP 2563996
        impacts 
          impact 
            freq 4
            norm 95
          impact 
            freq 15
            norm 109
          impact 
            freq 18
            norm 116
        impactsEnd 
  term uses
    doc 0
      freq 1
      pos 15815
    doc 1
      freq 6
      pos 781
      pos 3120
      pos 3588
      pos 7749
      pos 7799
      pos 7903
    doc 2
      freq 1
      pos 1873
    doc 3
      freq 2
      pos 1820
      pos 3335
    doc 4
      freq 1
      pos 288
    doc 5
      freq 1
      pos 2893
    doc 9
      freq 4
      pos 178
      pos 894
      pos 1174
      pos 1309
    doc 10
      freq 4
      pos 2439
      pos 2977
      pos 5888
      pos 11249
    doc 11
      freq 2
      pos 810
      pos 837
    doc 12
      freq 2
      pos 6604
      pos 9193
    doc 13
      freq 2
      pos 681
      pos 5227
    doc 15
      freq 1
      pos 1080
    doc 16
      freq 2
      pos 305
      pos 1416
    skipList 
      level 0
        skipDoc 10
        skipDocFP 2565491
        impacts 
          impact 
            freq 4
            norm 95
          impact 
            freq 6
            norm 113
        impactsEnd 
  term using
    doc 0
      freq 9
      pos 256
      pos 1474
      pos 3655
      pos 4171
      pos 5009
      pos 5107
      pos 5554
      pos 11013
      pos 16767
    doc 1
      freq 45
      pos 39
      pos 176
      pos 207
      pos 430
      pos 838
      pos 1067
      pos 1375
      pos 1868
      pos 2058
      pos 2074
      pos 2228
      pos 2424
      pos 2606
      pos 2698
      pos 2849
      pos 3057
      pos 3427
      pos 3612
      pos 3740
      pos 3840
      pos 3909
      pos 4246
      pos 4640
      pos 4861
      pos 5020
      pos 5299
      pos 5388
      pos 5691
      pos 6026
      pos 6280
      pos 6367
      pos 6762
      pos 7200
      pos 7294
      pos 7642
      pos 7892
      pos 8217
      pos 8240
      pos 8708
      pos 9023
      pos 9227
      pos 9334
      pos 9404
      pos 9499
      pos 9600
    doc 2
      freq 2
      pos 1796
      pos 2936
    doc 3
      freq 7
      pos 149
      pos 395
      pos 497
      pos 702
      pos 1551
      pos 1580
      pos 4374
    doc 4
      freq 7
      pos 342
      pos 963
      pos 4036
      pos 4061
      pos 4218
      pos 4609
      pos 4798
    doc 5
      freq 14
      pos 144
      pos 214
      pos 220
      pos 230
      pos 482
      pos 590
      pos 936
      pos 991
      pos 2204
      pos 2500
      pos 2814
      pos 2889
      pos 3035
      pos 3094
    doc 6
      freq 1
      pos 2515
    doc 7
      freq 12
      pos 715
      pos 1029
      pos 1044
      pos 1065
      pos 1075
      pos 1099
      pos 1169
      pos 2039
      pos 2574
      pos 2589
      pos 2649
      pos 2721
    doc 8
      freq 14
      pos 524
      pos 544
      pos 571
      pos 854
      pos 874
      pos 902
      pos 1180
      pos 1200
      pos 1227
      pos 1361
      pos 1381
      pos 1408
      pos 1550
      pos 1802
    doc 9
      freq 4
      pos 22
      pos 822
      pos 916
      pos 951
    doc 10
      freq 9
      pos 1281
      pos 2594
      pos 2617
      pos 2649
      pos 4559
      pos 6546
      pos 6756
      pos 7249
      pos 7899
    doc 11
      freq 4
      pos 736
      pos 1109
      pos 2130
      pos 9705
    doc 12
      freq 28
      pos 250
      pos 762
      pos 773
      pos 825
      pos 977
      pos 1106
      pos 1459
      pos 1956
      pos 2010
      pos 2089
      pos 2250
      pos 2345
      pos 2436
      pos 2483
      pos 2725
      pos 2733
      pos 4550
      pos 5271
      pos 5339
      pos 5695
      pos 6070
      pos 6739
      pos 8333
      pos 8485
      pos 8888
      pos 8961
      pos 9161
      pos 9322
    doc 13
      freq 9
      pos 423
      pos 444
      pos 604
      pos 1709
      pos 2595
      pos 3252
      pos 5238
      pos 5586
      pos 6621
    doc 14
      freq 11
      pos 235
      pos 244
      pos 252
      pos 260
      pos 1767
      pos 2187
      pos 2646
      pos 2957
      pos 4149
      pos 4877
      pos 5131
    doc 15
      freq 5
      pos 80
      pos 2397
      pos 2542
      pos 2552
      pos 3526
    doc 16
      freq 2
      pos 130
      pos 858
    doc 17
      freq 9
      pos 461
      pos 648
      pos 668
      pos 730
      pos 734
      pos 1699
      pos 1737
      pos 1794
      pos 1809
    doc 18
      freq 6
      pos 905
      pos 952
      pos 1114
      pos 1157
      pos 1734
      pos 1787
    skipList 
      level 0
        skipDoc 7
        skipDocFP 2566463
        impacts 
          impact 
            freq 12
            norm 100
          impact 
            freq 14
            norm 104
          impact 
            freq 45
            norm 113
        impactsEnd 
        skipDoc 15
        skipDocFP 2568085
        impacts 
          impact 
            freq 4
            norm 95
          impact 
            freq 14
            norm 97
          impact 
            freq 28
            norm 113
        impactsEnd 
  term usr
    doc 10
      freq 1
      pos 12391
    doc 11
      freq 1
      pos 9796
  term usual
    doc 10
      freq 2
      pos 3009
      pos 4072
  term usually
    doc 1
      freq 1
      pos 8685
    doc 10
      freq 1
      pos 7585
    doc 11
      freq 1
      pos 1601
    doc 12
      freq 1
      pos 2718
  term ut
    doc 11
      freq 1
      pos 6134
  term utc
    doc 5
      freq 2
      pos 1992
      pos 2377
    doc 11
      freq 1
      pos 6144
  term utf
    doc 1
      freq 1
      pos 6277
    doc 11
      freq 3
      pos 1013
      pos 1738
      pos 3963
  term utf8
    doc 11
      freq 3
      pos 1848
      pos 3949
      pos 3951
  term utg7d
    doc 11
      freq 1
      pos 10287
  term utility
    doc 2
      freq 1
      pos 1530
    doc 10
      freq 1
      pos 12444
    doc 11
      freq 1
      pos 9851
    doc 17
      freq 1
      pos 1671
  term utiliz
    doc 2
      freq 1
      pos 564
    doc 10
      freq 1
      pos 10476
  term utilization
    doc 6
      freq 1
      pos 1674
  term utilized
    doc 2
      freq 3
      pos 4919
      pos 5646
      pos 5726
  term utilizes
    doc 10
      freq 1
      pos 889
  term utilizing
    doc 2
      freq 1
      pos 1298
    doc 5
      freq 1
      pos 733
    doc 10
      freq 2
      pos 6008
      pos 6036
  term uuc51gnk2kgkgxqqthopbcew9yfecrfhvdl7jpagatei5izwggqqdvovhun1h
    doc 10
      freq 1
      pos 6223
  term uuq
    doc 11
      freq 1
      pos 9996
  term uur8cwgddfybkr2f0op5bli2jalde8biguvlyb
    doc 10
      freq 1
      pos 12625
  term uvlf3shaeou9kng98mjno5pobpm9s20e9iu2zrbv
    doc 10
      freq 1
      pos 12583
  term uvpbicbs6ugk5kg4wyqo6y2gw45qaahrgqdrj6ag6bu06keyhh1eyl7gbzuk
    doc 11
      freq 1
      pos 9970
  term uyb9mqtvanlyfvr98kw8ftosvrwlja5oh5xmiipna2lq4hsjkvkqucmhl
    doc 10
      freq 1
      pos 6255
  term uzqpgcklcyzsj5f2tooc0
    doc 10
      freq 1
      pos 12664
  term v
    doc 1
      freq 6
      pos 1021
      pos 1022
      pos 1023
      pos 1024
      pos 1026
      pos 1029
    doc 2
      freq 1
      pos 2304
    doc 3
      freq 6
      pos 595
      pos 596
      pos 597
      pos 598
      pos 601
      pos 604
    doc 4
      freq 1
      pos 5308
    doc 5
      freq 1
      pos 4305
    doc 6
      freq 2
      pos 2995
      pos 3070
    doc 8
      freq 1
      pos 2086
    doc 10
      freq 3
      pos 6373
      pos 6498
      pos 6673
    doc 11
      freq 29
      pos 1509
      pos 1532
      pos 2242
      pos 2250
      pos 2925
      pos 2931
      pos 2985
      pos 2991
      pos 2997
      pos 3003
      pos 3168
      pos 3401
      pos 4044
      pos 4309
      pos 4490
      pos 4704
      pos 5195
      pos 5352
      pos 5500
      pos 5660
      pos 5980
      pos 6204
      pos 6894
      pos 7228
      pos 8184
      pos 8513
      pos 9108
      pos 9285
      pos 10061
    doc 12
      freq 1
      pos 7265
    doc 13
      freq 1
      pos 6761
    skipList 
      level 0
        skipDoc 10
        skipDocFP 2572327
        impacts 
          impact 
            freq 1
            norm 97
          impact 
            freq 2
            norm 101
          impact 
            freq 6
            norm 107
        impactsEnd 
  term v0
    doc 11
      freq 1
      pos 10328
  term v3vuz
    doc 11
      freq 1
      pos 10270
  term v4addr
    doc 12
      freq 2
      pos 1412
      pos 1418
  term v4aitculyd4lr0rz3quy
    doc 11
      freq 1
      pos 10505
  term v5
    doc 7
      freq 2
      pos 2417
      pos 2804
  term v5p7rd03wpit
    doc 10
      freq 1
      pos 12801
  term v72j
    doc 11
      freq 1
      pos 10351
  term v9yzanu4
    doc 10
      freq 1
      pos 12751
  term v9zlf8cyleletizhwnlhsxj
    doc 11
      freq 1
      pos 9992
  term va
    doc 1
      freq 1
      pos 9348
    doc 3
      freq 2
      pos 4851
      pos 4909
    doc 10
      freq 1
      pos 12539
  term vach
    doc 1
      freq 1
      pos 8880
  term vainshtein
    doc 1
      freq 1
      pos 8997
    doc 8
      freq 2
      pos 1887
      pos 2010
  term valid
    doc 1
      freq 1
      pos 4651
    doc 4
      freq 1
      pos 4445
    doc 10
      freq 8
      pos 2994
      pos 4085
      pos 7927
      pos 8497
      pos 8535
      pos 8941
      pos 9506
      pos 11436
    doc 11
      freq 14
      pos 133
      pos 146
      pos 150
      pos 648
      pos 689
      pos 1197
      pos 1584
      pos 2003
      pos 2024
      pos 2170
      pos 2620
      pos 6143
      pos 7581
      pos 7804
    doc 13
      freq 1
      pos 6617
    doc 14
      freq 1
      pos 450
    doc 16
      freq 1
      pos 977
    doc 17
      freq 1
      pos 612
    skipList 
      level 0
        skipDoc 17
        skipDocFP 2574496
        impacts 
          impact 
            freq 1
            norm 98
          impact 
            freq 14
            norm 114
        impactsEnd 
  term validat
    doc 1
      freq 2
      pos 3973
      pos 5984
    doc 3
      freq 1
      pos 1953
    doc 10
      freq 7
      pos 2038
      pos 3055
      pos 4249
      pos 4732
      pos 6027
      pos 11758
      pos 12905
    doc 13
      freq 4
      pos 5863
      pos 5877
      pos 5929
      pos 5986
  term validated
    doc 10
      freq 4
      pos 969
      pos 1424
      pos 4110
      pos 4123
    doc 16
      freq 1
      pos 2476
  term validates
    doc 10
      freq 1
      pos 1863
  term validating
    doc 10
      freq 1
      pos 150
    doc 17
      freq 1
      pos 122
  term validation
    doc 0
      freq 1
      pos 8206
    doc 4
      freq 2
      pos 4605
      pos 4626
    doc 5
      freq 1
      pos 402
    doc 10
      freq 2
      pos 2071
      pos 3130
    doc 11
      freq 1
      pos 9539
    doc 12
      freq 1
      pos 6873
    doc 17
      freq 1
      pos 1859
  term validators
    doc 18
      freq 2
      pos 713
      pos 1770
  term validity
    doc 0
      freq 1
      pos 17341
    doc 1
      freq 1
      pos 9722
    doc 2
      freq 1
      pos 6519
    doc 3
      freq 1
      pos 6071
    doc 4
      freq 1
      pos 6226
    doc 5
      freq 1
      pos 4556
    doc 6
      freq 1
      pos 3356
    doc 7
      freq 1
      pos 3061
    doc 8
      freq 1
      pos 2278
    doc 9
      freq 3
      pos 203
      pos 334
      pos 1923
    doc 10
      freq 4
      pos 3276
      pos 4293
      pos 4638
      pos 13584
    doc 11
      freq 1
      pos 10745
    doc 12
      freq 1
      pos 9595
    doc 13
      freq 2
      pos 6510
      pos 7210
    doc 14
      freq 1
      pos 5676
    doc 15
      freq 1
      pos 4195
    doc 16
      freq 1
      pos 2806
    doc 17
      freq 2
      pos 1547
      pos 2530
    doc 18
      freq 1
      pos 2318
    skipList 
      level 0
        skipDoc 7
        skipDocFP 2576340
        impacts 
          impact 
            freq 1
            norm 100
        impactsEnd 
        skipDoc 15
        skipDocFP 2576645
        impacts 
          impact 
            freq 3
            norm 95
          impact 
            freq 4
            norm 116
        impactsEnd 
  term validly
    doc 18
      freq 1
      pos 1929
  term valuabl
    doc 0
      freq 1
      pos 15909
  term value
    doc 0
      freq 89
      pos 706
      pos 2128
      pos 2138
      pos 2167
      pos 2401
      pos 2420
      pos 2444
      pos 2484
      pos 2571
      pos 2577
      pos 2623
      pos 2744
      pos 2749
      pos 2817
      pos 3063
      pos 3098
      pos 3278
      pos 3306
      pos 3730
      pos 3762
      pos 3817
      pos 3839
      pos 3913
      pos 3935
      pos 3966
      pos 4242
      pos 4256
      pos 4317
      pos 4339
      pos 4425
      pos 4882
      pos 4895
      pos 4911
      pos 5284
      pos 5304
      pos 5312
      pos 5351
      pos 5544
      pos 5550
      pos 5560
      pos 5601
      pos 5709
      pos 5777
      pos 6068
      pos 6112
      pos 6223
      pos 6236
      pos 6412
      pos 6454
      pos 6529
      pos 6563
      pos 6589
      pos 6635
      pos 6670
      pos 6689
      pos 6703
      pos 6762
      pos 6791
      pos 6865
      pos 6883
      pos 7634
      pos 8936
      pos 8950
      pos 9268
      pos 9783
      pos 10088
      pos 10144
      pos 10428
      pos 10449
      pos 10479
      pos 10657
      pos 10673
      pos 11139
      pos 11181
      pos 11203
      pos 11337
      pos 11443
      pos 11509
      pos 11573
      pos 11990
      pos 12269
      pos 12563
      pos 13092
      pos 13206
      pos 13972
      pos 13990
      pos 14001
      pos 14331
      pos 15832
    doc 1
      freq 28
      pos 791
      pos 1603
      pos 1634
      pos 2510
      pos 2598
      pos 2632
      pos 2909
      pos 2925
      pos 3684
      pos 3686
      pos 3691
      pos 3693
      pos 3698
      pos 3700
      pos 3767
      pos 3832
      pos 3932
      pos 4048
      pos 4051
      pos 4118
      pos 4128
      pos 6072
      pos 6075
      pos 6143
      pos 6438
      pos 6450
      pos 6795
      pos 7828
    doc 3
      freq 12
      pos 1150
      pos 1940
      pos 2023
      pos 2265
      pos 2715
      pos 3521
      pos 3757
      pos 3804
      pos 3917
      pos 3922
      pos 5072
      pos 5562
    doc 4
      freq 13
      pos 250
      pos 318
      pos 558
      pos 571
      pos 637
      pos 894
      pos 1300
      pos 3171
      pos 3511
      pos 4752
      pos 4788
      pos 4968
      pos 5911
    doc 5
      freq 25
      pos 1688
      pos 1695
      pos 1707
      pos 1711
      pos 1775
      pos 1787
      pos 1832
      pos 1850
      pos 1854
      pos 1859
      pos 2011
      pos 2021
      pos 2102
      pos 2124
      pos 2313
      pos 2348
      pos 2378
      pos 2682
      pos 2685
      pos 3838
      pos 3848
      pos 3868
      pos 3878
      pos 4051
      pos 4059
    doc 6
      freq 3
      pos 164
      pos 1317
      pos 1396
    doc 8
      freq 6
      pos 366
      pos 436
      pos 621
      pos 1161
      pos 1342
      pos 1577
    doc 9
      freq 8
      pos 468
      pos 832
      pos 906
      pos 920
      pos 1153
      pos 1177
      pos 1434
      pos 1477
    doc 10
      freq 29
      pos 1032
      pos 1881
      pos 1892
      pos 2068
      pos 2359
      pos 2654
      pos 3294
      pos 3533
      pos 3535
      pos 3998
      pos 4285
      pos 4430
      pos 5172
      pos 5356
      pos 5369
      pos 5383
      pos 5454
      pos 7170
      pos 7816
      pos 7994
      pos 8045
      pos 8149
      pos 8154
      pos 8175
      pos 8838
      pos 11081
      pos 12035
      pos 12064
      pos 12071
    doc 11
      freq 55
      pos 451
      pos 470
      pos 953
      pos 956
      pos 961
      pos 964
      pos 970
      pos 973
      pos 975
      pos 1063
      pos 1067
      pos 1113
      pos 1128
      pos 1171
      pos 1290
      pos 1331
      pos 1338
      pos 1418
      pos 1492
      pos 1495
      pos 1505
      pos 1508
      pos 1695
      pos 1715
      pos 1732
      pos 1747
      pos 1760
      pos 1850
      pos 2085
      pos 2087
      pos 2094
      pos 2500
      pos 2645
      pos 2823
      pos 2866
      pos 2901
      pos 2917
      pos 3474
      pos 4533
      pos 4594
      pos 4631
      pos 4770
      pos 4776
      pos 4786
      pos 4875
      pos 4878
      pos 5002
      pos 6096
      pos 8079
      pos 8261
      pos 8264
      pos 8378
      pos 8564
      pos 8594
      pos 9190
    doc 12
      freq 1
      pos 1356
    doc 14
      freq 35
      pos 727
      pos 762
      pos 795
      pos 809
      pos 867
      pos 893
      pos 939
      pos 986
      pos 1001
      pos 1023
      pos 1057
      pos 1453
      pos 1500
      pos 1509
      pos 1542
      pos 1638
      pos 1653
      pos 1675
      pos 1709
      pos 1747
      pos 1962
      pos 1984
      pos 2031
      pos 2041
      pos 2060
      pos 2191
      pos 2201
      pos 2252
      pos 3247
      pos 3283
      pos 4316
      pos 4446
      pos 5004
      pos 5021
      pos 5173
    doc 15
      freq 3
      pos 987
      pos 2110
      pos 2126
    doc 17
      freq 1
      pos 629
    doc 18
      freq 4
      pos 1290
      pos 1317
      pos 1324
      pos 1839
    skipList 
      level 0
        skipDoc 9
        skipDocFP 2577662
        impacts 
          impact 
            freq 8
            norm 95
          impact 
            freq 25
            norm 104
          impact 
            freq 28
            norm 113
          impact 
            freq 89
            norm 120
        impactsEnd 
  term value's
    doc 11
      freq 2
      pos 1671
      pos 8390
  term values
    doc 0
      freq 26
      pos 1671
      pos 2050
      pos 2085
      pos 2368
      pos 2432
      pos 2450
      pos 2511
      pos 2592
      pos 2644
      pos 2694
      pos 2757
      pos 2791
      pos 2839
      pos 2926
      pos 2930
      pos 3014
      pos 3792
      pos 4304
      pos 4690
      pos 5849
      pos 5856
      pos 6325
      pos 6550
      pos 10282
      pos 11168
      pos 15822
    doc 1
      freq 7
      pos 2518
      pos 3713
      pos 3719
      pos 3739
      pos 6082
      pos 7772
      pos 7822
    doc 2
      freq 1
      pos 6173
    doc 3
      freq 2
      pos 1992
      pos 2682
    doc 4
      freq 23
      pos 714
      pos 832
      pos 864
      pos 882
      pos 967
      pos 978
      pos 1974
      pos 2211
      pos 3098
      pos 4768
      pos 4780
      pos 4789
      pos 4872
      pos 4936
      pos 5008
      pos 5012
      pos 5028
      pos 5049
      pos 5100
      pos 5127
      pos 5314
      pos 5724
      pos 5884
    doc 5
      freq 19
      pos 1199
      pos 1875
      pos 1889
      pos 1896
      pos 1904
      pos 1980
      pos 2094
      pos 2120
      pos 2673
      pos 3237
      pos 3775
      pos 3803
      pos 3826
      pos 3895
      pos 3939
      pos 3962
      pos 3982
      pos 4019
      pos 4037
    doc 6
      freq 4
      pos 1074
      pos 1625
      pos 1722
      pos 1886
    doc 7
      freq 1
      pos 1700
    doc 8
      freq 17
      pos 78
      pos 354
      pos 499
      pos 502
      pos 514
      pos 534
      pos 554
      pos 830
      pos 885
      pos 1158
      pos 1170
      pos 1190
      pos 1210
      pos 1339
      pos 1351
      pos 1371
      pos 1391
    doc 9
      freq 2
      pos 854
      pos 1441
    doc 10
      freq 9
      pos 355
      pos 2847
      pos 4653
      pos 4659
      pos 5462
      pos 10125
      pos 12009
      pos 12022
      pos 12075
    doc 11
      freq 31
      pos 199
      pos 272
      pos 280
      pos 448
      pos 459
      pos 1008
      pos 1098
      pos 1232
      pos 1245
      pos 1377
      pos 2488
      pos 2710
      pos 2723
      pos 2725
      pos 2750
      pos 2762
      pos 3568
      pos 3604
      pos 4240
      pos 4744
      pos 4752
      pos 4835
      pos 4850
      pos 4865
      pos 4952
      pos 4960
      pos 6735
      pos 8076
      pos 8097
      pos 8236
      pos 8243
    doc 12
      freq 2
      pos 2809
      pos 3038
    doc 14
      freq 18
      pos 826
      pos 1028
      pos 1166
      pos 1519
      pos 1680
      pos 1932
      pos 2049
      pos 2100
      pos 2107
      pos 2141
      pos 2145
      pos 2216
      pos 2273
      pos 2917
      pos 2922
      pos 2933
      pos 3563
      pos 4531
    doc 15
      freq 3
      pos 2030
      pos 2050
      pos 2226
    doc 17
      freq 1
      pos 1534
    skipList 
      level 0
        skipDoc 7
        skipDocFP 2583121
        impacts 
          impact 
            freq 1
            norm 100
          impact 
            freq 4
            norm 101
          impact 
            freq 19
            norm 104
          impact 
            freq 23
            norm 108
          impact 
            freq 26
            norm 120
        impactsEnd 
        skipDoc 17
        skipDocFP 2584550
        impacts 
          impact 
            freq 2
            norm 95
          impact 
            freq 17
            norm 97
          impact 
            freq 18
            norm 107
          impact 
            freq 31
            norm 114
        impactsEnd 
  term van
    doc 12
      freq 1
      pos 6809
  term vancouver
    doc 2
      freq 1
      pos 375
  term vanson
    doc 1
      freq 1
      pos 8882
  term variabl
    doc 0
      freq 10
      pos 2239
      pos 2358
      pos 2501
      pos 4788
      pos 4998
      pos 5008
      pos 5066
      pos 7062
      pos 10748
      pos 16210
    doc 1
      freq 7
      pos 2768
      pos 3152
      pos 4046
      pos 4049
      pos 6070
      pos 6073
      pos 6260
    doc 3
      freq 1
      pos 1349
    doc 5
      freq 3
      pos 1750
      pos 1855
      pos 2722
    doc 6
      freq 5
      pos 594
      pos 600
      pos 671
      pos 1216
      pos 1668
  term variables
    doc 0
      freq 1
      pos 4683
  term variant
    doc 5
      freq 1
      pos 840
    doc 14
      freq 3
      pos 2763
      pos 2786
      pos 2836
    doc 15
      freq 1
      pos 762
  term variants
    doc 5
      freq 1
      pos 2228
    doc 14
      freq 1
      pos 2701
  term variation
    doc 6
      freq 3
      pos 688
      pos 1596
      pos 3017
  term variations
    doc 6
      freq 1
      pos 1378
    doc 15
      freq 2
      pos 248
      pos 1523
  term varied
    doc 11
      freq 2
      pos 223
      pos 3557
  term varies
    doc 13
      freq 2
      pos 4949
      pos 6669
  term various
    doc 2
      freq 1
      pos 5910
    doc 3
      freq 3
      pos 4122
      pos 5434
      pos 5570
    doc 4
      freq 1
      pos 4105
    doc 6
      freq 4
      pos 690
      pos 712
      pos 948
      pos 1677
    doc 10
      freq 4
      pos 1744
      pos 2945
      pos 6174
      pos 10122
    doc 12
      freq 1
      pos 556
    doc 13
      freq 2
      pos 711
      pos 3704
    doc 14
      freq 1
      pos 2561
    doc 17
      freq 1
      pos 177
    skipList 
      level 0
        skipDoc 14
        skipDocFP 2588017
        impacts 
          impact 
            freq 4
            norm 101
        impactsEnd 
  term vary
    doc 6
      freq 1
      pos 1430
    doc 13
      freq 1
      pos 3896
    doc 15
      freq 1
      pos 1346
  term varying
    doc 6
      freq 1
      pos 952
    doc 10
      freq 1
      pos 10437
    doc 12
      freq 1
      pos 656
  term vasil
    doc 1
      freq 2
      pos 9311
      pos 9322
    doc 3
      freq 2
      pos 4812
      pos 4823
  term vat66solsr5dmvaewdibw
    doc 11
      freq 1
      pos 10479
  term vatgrhx4fb9sh
    doc 11
      freq 1
      pos 10435
  term vb
    doc 6
      freq 20
      pos 1700
      pos 1721
      pos 1723
      pos 1727
      pos 1732
      pos 1744
      pos 1747
      pos 1782
      pos 1797
      pos 1816
      pos 1885
      pos 1890
      pos 1893
      pos 1897
      pos 1900
      pos 1906
      pos 1919
      pos 1921
      pos 1974
      pos 2016
  term vc
    doc 1
      freq 1
      pos 1580
  term vcc
    doc 8
      freq 4
      pos 641
      pos 678
      pos 701
      pos 718
  term vccv
    doc 3
      freq 5
      pos 1581
      pos 3313
      pos 3314
      pos 4661
      pos 4675
    doc 8
      freq 4
      pos 1092
      pos 1094
      pos 1812
      pos 1824
  term vcdtr4p
    doc 11
      freq 1
      pos 9954
  term vci
    doc 1
      freq 1
      pos 1602
  term vdoe8hymqow
    doc 10
      freq 1
      pos 6839
  term vei
    doc 7
      freq 1
      pos 2924
  term venaas
    doc 15
      freq 3
      pos 15
      pos 4037
      pos 4044
  term vendor
    doc 2
      freq 4
      pos 1553
      pos 1566
      pos 2405
      pos 6158
    doc 5
      freq 2
      pos 2687
      pos 2690
    doc 8
      freq 10
      pos 275
      pos 280
      pos 561
      pos 596
      pos 892
      pos 974
      pos 1217
      pos 1268
      pos 1398
      pos 1463
  term vendor's
    doc 2
      freq 1
      pos 1592
  term venkataramanan
    doc 11
      freq 1
      pos 9456
  term venkatesh
    doc 11
      freq 1
      pos 9455
  term verification
    doc 3
      freq 1
      pos 4674
    doc 8
      freq 1
      pos 1823
    doc 10
      freq 3
      pos 3240
      pos 3838
      pos 7751
    doc 16
      freq 1
      pos 1123
    doc 17
      freq 3
      pos 180
      pos 193
      pos 1934
  term verified
    doc 9
      freq 1
      pos 343
    doc 10
      freq 2
      pos 11401
      pos 12887
    doc 12
      freq 1
      pos 5361
  term verifier
    doc 10
      freq 29
      pos 209
      pos 3792
      pos 3809
      pos 3914
      pos 3928
      pos 4015
      pos 4066
      pos 4143
      pos 4154
      pos 4193
      pos 4218
      pos 4247
      pos 5664
      pos 5677
      pos 6023
      pos 9501
      pos 10370
      pos 10740
      pos 11099
      pos 11184
      pos 11237
      pos 11267
      pos 11574
      pos 11674
      pos 11683
      pos 11756
      pos 11788
      pos 11869
      pos 11888
  term verifiers
    doc 10
      freq 9
      pos 2271
      pos 2294
      pos 3185
      pos 6104
      pos 8573
      pos 8608
      pos 8631
      pos 10970
      pos 11363
    doc 17
      freq 2
      pos 1805
      pos 1887
  term verifies
    doc 10
      freq 1
      pos 2027
    doc 13
      freq 1
      pos 6611
  term verify
    doc 0
      freq 1
      pos 12018
    doc 9
      freq 1
      pos 185
    doc 10
      freq 12
      pos 491
      pos 1620
      pos 2315
      pos 3268
      pos 3824
      pos 3900
      pos 4195
      pos 4268
      pos 4625
      pos 4688
      pos 5967
      pos 6791
  term verifying
    doc 10
      freq 1
      pos 10793
    doc 17
      freq 1
      pos 1367
  term vermeulen
    doc 0
      freq 1
      pos 15967
  term vermont
    doc 0
      freq 2
      pos 1114
      pos 17206
  term versa
    doc 12
      freq 1
      pos 1080
    doc 15
      freq 2
      pos 1535
      pos 3763
  term version
    doc 0
      freq 10
      pos 1169
      pos 1216
      pos 1242
      pos 2299
      pos 2311
      pos 12027
      pos 12488
      pos 13615
      pos 15863
      pos 17051
    doc 2
      freq 4
      pos 2011
      pos 4576
      pos 4606
      pos 4719
    doc 3
      freq 1
      pos 4725
    doc 4
      freq 8
      pos 37
      pos 130
      pos 285
      pos 5184
      pos 5205
      pos 5242
      pos 5337
      pos 5359
    doc 5
      freq 1
      pos 4293
    doc 6
      freq 1
      pos 2885
    doc 7
      freq 12
      pos 768
      pos 909
      pos 1373
      pos 2016
      pos 2158
      pos 2373
      pos 2714
      pos 2739
      pos 2748
      pos 2795
      pos 2813
      pos 2827
    doc 9
      freq 1
      pos 1751
    doc 11
      freq 7
      pos 362
      pos 582
      pos 759
      pos 5725
      pos 6640
      pos 6654
      pos 6666
    doc 12
      freq 9
      pos 906
      pos 1052
      pos 1063
      pos 3325
      pos 7211
      pos 7252
      pos 7274
      pos 7430
      pos 9183
    doc 13
      freq 2
      pos 5605
      pos 5609
    doc 15
      freq 7
      pos 108
      pos 136
      pos 340
      pos 1142
      pos 1538
      pos 1803
      pos 3993
    doc 16
      freq 4
      pos 1900
      pos 2004
      pos 2372
      pos 2529
    skipList 
      level 0
        skipDoc 9
        skipDocFP 2592483
        impacts 
          impact 
            freq 1
            norm 95
          impact 
            freq 12
            norm 100
        impactsEnd 
  term versioning
    doc 13
      freq 1
      pos 660
  term versions
    doc 0
      freq 2
      pos 16748
      pos 16802
    doc 2
      freq 1
      pos 4878
    doc 6
      freq 1
      pos 3170
    doc 11
      freq 3
      pos 9162
      pos 9458
      pos 9544
    doc 13
      freq 4
      pos 5517
      pos 5636
      pos 6562
      pos 6584
    doc 15
      freq 1
      pos 3224
  term vertical
    doc 10
      freq 2
      pos 4903
      pos 7203
  term very
    doc 1
      freq 3
      pos 2706
      pos 4759
      pos 8734
    doc 2
      freq 2
      pos 1858
      pos 4516
    doc 7
      freq 1
      pos 1794
    doc 9
      freq 1
      pos 1588
    doc 10
      freq 6
      pos 852
      pos 1347
      pos 1727
      pos 5893
      pos 8068
      pos 10256
    doc 11
      freq 6
      pos 1095
      pos 2728
      pos 2766
      pos 2817
      pos 2831
      pos 3140
    doc 12
      freq 6
      pos 2752
      pos 3043
      pos 3636
      pos 6875
      pos 6953
      pos 9256
    doc 13
      freq 5
      pos 2740
      pos 4055
      pos 4343
      pos 5457
      pos 6670
    doc 15
      freq 1
      pos 1705
    doc 17
      freq 1
      pos 1929
    skipList 
      level 0
        skipDoc 13
        skipDocFP 2594488
        impacts 
          impact 
            freq 1
            norm 95
          impact 
            freq 2
            norm 108
          impact 
            freq 5
            norm 109
          impact 
            freq 6
            norm 113
        impactsEnd 
  term vf6fwp
    doc 11
      freq 1
      pos 10184
  term vfcxh
    doc 11
      freq 1
      pos 10094
  term vfuxj
    doc 11
      freq 1
      pos 10346
  term vfzgsblz4976xruxlzxyntpugmrayuavo6v3
    doc 11
      freq 1
      pos 10231
  term vh2t7dzuc
    doc 10
      freq 1
      pos 12577
  term vh3tgas
    doc 10
      freq 1
      pos 6212
  term vhgsd
    doc 11
      freq 1
      pos 10193
  term via
    doc 0
      freq 2
      pos 226
      pos 3394
    doc 1
      freq 3
      pos 4356
      pos 5220
      pos 8531
    doc 2
      freq 4
      pos 750
      pos 2409
      pos 6108
      pos 6155
    doc 5
      freq 3
      pos 237
      pos 2242
      pos 2944
    doc 6
      freq 1
      pos 2605
    doc 9
      freq 1
      pos 496
    doc 10
      freq 19
      pos 560
      pos 1376
      pos 6326
      pos 6611
      pos 6978
      pos 7115
      pos 7328
      pos 8835
      pos 8853
      pos 8860
      pos 8896
      pos 8912
      pos 8919
      pos 8964
      pos 8998
      pos 9026
      pos 9042
      pos 9062
      pos 10078
    doc 11
      freq 89
      pos 467
      pos 1482
      pos 1932
      pos 2222
      pos 2383
      pos 2575
      pos 2699
      pos 2919
      pos 2937
      pos 2943
      pos 2949
      pos 2955
      pos 2961
      pos 2967
      pos 2973
      pos 2979
      pos 3009
      pos 3015
      pos 3021
      pos 3027
      pos 3033
      pos 3039
      pos 3059
      pos 3065
      pos 3071
      pos 3077
      pos 3083
      pos 3089
      pos 3095
      pos 3101
      pos 3107
      pos 3113
      pos 3119
      pos 3125
      pos 3132
      pos 3353
      pos 3387
      pos 3547
      pos 3565
      pos 3638
      pos 3646
      pos 3654
      pos 3662
      pos 3670
      pos 3777
      pos 4009
      pos 4133
      pos 4226
      pos 4293
      pos 4473
      pos 4686
      pos 4881
      pos 4905
      pos 5026
      pos 5180
      pos 5336
      pos 5481
      pos 5641
      pos 5793
      pos 5963
      pos 6177
      pos 6366
      pos 6439
      pos 6601
      pos 6678
      pos 6786
      pos 6881
      pos 6971
      pos 7116
      pos 7215
      pos 7398
      pos 7529
      pos 7660
      pos 7762
      pos 7873
      pos 8059
      pos 8131
      pos 8320
      pos 8375
      pos 8387
      pos 8471
      pos 8478
      pos 8620
      pos 8729
      pos 8819
      pos 8936
      pos 9094
      pos 9187
      pos 9249
    doc 12
      freq 2
      pos 2179
      pos 7151
    doc 13
      freq 2
      pos 1766
      pos 5534
    doc 15
      freq 10
      pos 99
      pos 369
      pos 394
      pos 685
      pos 1948
      pos 2636
      pos 2861
      pos 2875
      pos 2881
      pos 3369
    doc 16
      freq 2
      pos 1960
      pos 2328
    doc 18
      freq 1
      pos 440
    skipList 
      level 0
        skipDoc 11
        skipDocFP 2595964
        impacts 
          impact 
            freq 1
            norm 95
          impact 
            freq 3
            norm 104
          impact 
            freq 4
            norm 108
          impact 
            freq 89
            norm 114
        impactsEnd 
  term vice
    doc 12
      freq 1
      pos 1079
    doc 15
      freq 2
      pos 1534
      pos 3762
  term video
    doc 6
      freq 8
      pos 210
      pos 358
      pos 405
      pos 448
      pos 558
      pos 1020
      pos 1240
      pos 2913
    doc 11
      freq 19
      pos 1557
      pos 2275
      pos 3193
      pos 3426
      pos 4069
      pos 4334
      pos 4515
      pos 4729
      pos 5220
      pos 5377
      pos 5525
      pos 5685
      pos 6005
      pos 6229
      pos 6915
      pos 7253
      pos 8209
      pos 8538
      pos 9133
    doc 13
      freq 10
      pos 533
      pos 920
      pos 925
      pos 929
      pos 2878
      pos 2895
      pos 2918
      pos 3113
      pos 3163
      pos 6805
  term vidhi
    doc 11
      freq 1
      pos 9486
  term vidtrans
    doc 6
      freq 1
      pos 2917
  term view
    doc 3
      freq 3
      pos 4967
      pos 4981
      pos 5817
    doc 7
      freq 1
      pos 440
    doc 9
      freq 1
      pos 1774
    doc 10
      freq 1
      pos 11255
    doc 12
      freq 1
      pos 7977
  term viewed
    doc 13
      freq 1
      pos 577
    doc 15
      freq 1
      pos 853
  term viewing
    doc 10
      freq 1
      pos 2600
  term views
    doc 15
      freq 1
      pos 3872
  term vijay
    doc 11
      freq 2
      pos 9435
      pos 9475
  term vijayabhaskar
    doc 15
      freq 1
      pos 3846
  term vinai
    doc 1
      freq 1
      pos 9297
    doc 3
      freq 2
      pos 4796
      pos 4810
  term vines
    doc 7
      freq 2
      pos 1082
      pos 2675
  term violat
    doc 10
      freq 1
      pos 9217
  term violates
    doc 12
      freq 1
      pos 8663
  term violation
    doc 10
      freq 1
      pos 8025
  term virtual
    doc 0
      freq 3
      pos 228
      pos 5985
      pos 6037
    doc 1
      freq 3
      pos 2663
      pos 2680
      pos 4465
    doc 2
      freq 3
      pos 2568
      pos 3009
      pos 3403
    doc 3
      freq 7
      pos 1221
      pos 4157
      pos 4460
      pos 4671
      pos 4704
      pos 5122
      pos 5150
    doc 6
      freq 3
      pos 1698
      pos 1787
      pos 1802
    doc 8
      freq 1
      pos 1820
    doc 10
      freq 2
      pos 10451
      pos 10721
  term virtually
    doc 7
      freq 1
      pos 383
  term visibl
    doc 0
      freq 2
      pos 16676
      pos 16693
    doc 1
      freq 1
      pos 1536
    doc 12
      freq 1
      pos 1105
    doc 17
      freq 1
      pos 204
  term viswanathan
    doc 3
      freq 1
      pos 4388
  term vixie
    doc 12
      freq 3
      pos 7012
      pos 7087
      pos 7491
    doc 14
      freq 1
      pos 5408
  term vl7oqes
    doc 10
      freq 1
      pos 6227
  term vlachos
    doc 1
      freq 1
      pos 9187
  term vlan
    doc 1
      freq 2
      pos 1660
      pos 3279
    doc 2
      freq 4
      pos 249
      pos 4171
      pos 4196
      pos 4705
    doc 3
      freq 48
      pos 639
      pos 729
      pos 730
      pos 998
      pos 1145
      pos 1194
      pos 1293
      pos 1299
      pos 1301
      pos 1315
      pos 1338
      pos 1343
      pos 1448
      pos 1474
      pos 1479
      pos 1481
      pos 1505
      pos 1546
      pos 1641
      pos 1664
      pos 1723
      pos 1748
      pos 2015
      pos 2027
      pos 2045
      pos 2060
      pos 2065
      pos 2074
      pos 2083
      pos 2092
      pos 2342
      pos 2403
      pos 2557
      pos 2577
      pos 2588
      pos 2800
      pos 3798
      pos 3898
      pos 5067
      pos 5071
      pos 5169
      pos 5175
      pos 5180
      pos 5239
      pos 5261
      pos 5452
      pos 5463
      pos 5507
    doc 8
      freq 1
      pos 1054
  term vlans
    doc 3
      freq 1
      pos 5133
  term vleeschouwer
    doc 0
      freq 1
      pos 15970
  term vlo
    doc 11
      freq 1
      pos 10438
  term vlxa
    doc 10
      freq 1
      pos 12489
  term vmgjcp
    doc 10
      freq 1
      pos 12587
  term vn1yqcs4s6zk8mtolopvt6
    doc 10
      freq 1
      pos 12657
  term vo2qr1smwsrtbu
    doc 11
      freq 1
      pos 10103
  term vogelsang
    doc 1
      freq 1
      pos 9251
    doc 3
      freq 1
      pos 4781
  term voice
    doc 1
      freq 1
      pos 608
    doc 3
      freq 1
      pos 5763
    doc 6
      freq 2
      pos 211
      pos 1022
    doc 10
      freq 1
      pos 7403
  term voip
    doc 10
      freq 1
      pos 7406
  term vollbrecht
    doc 2
      freq 3
      pos 2959
      pos 3268
      pos 3328
  term volum
    doc 9
      freq 1
      pos 516
  term volunteers
    doc 2
      freq 1
      pos 4756
  term volz
    doc 12
      freq 2
      pos 7176
      pos 7865
    doc 15
      freq 2
      pos 3844
      pos 3942
  term vot0wu8s
    doc 11
      freq 1
      pos 10086
  term voting
    doc 2
      freq 2
      pos 1817
      pos 5389
  term vouch
    doc 10
      freq 1
      pos 9205
  term vpc
    doc 8
      freq 2
      pos 687
      pos 710
  term vpi
    doc 1
      freq 1
      pos 1601
  term vpls
    doc 1
      freq 2
      pos 4511
      pos 4522
  term vpn
    doc 1
      freq 2
      pos 3275
      pos 4517
    doc 3
      freq 1
      pos 4707
  term vpws
    doc 1
      freq 1
      pos 4469
  term vqqkdarjrvrgmrswgqydvqqddbjiawxvegkuzxhhbxbszs5jb22caqawdaydvr0t
    doc 10
      freq 1
      pos 6905
  term vr0dt1jhq
    doc 11
      freq 1
      pos 10298
  term vs
    doc 3
      freq 2
      pos 225
      pos 2327
    doc 4
      freq 1
      pos 2013
    doc 10
      freq 1
      pos 12733
    doc 12
      freq 2
      pos 265
      pos 2287
  term vs2ypshfremj1dtmymamdflxuqhlpgjqej
    doc 10
      freq 1
      pos 12606
  term vsa
    doc 2
      freq 2
      pos 1633
      pos 1636
  term vsas
    doc 2
      freq 3
      pos 1556
      pos 1605
      pos 6161
  term vsirkay
    doc 1
      freq 1
      pos 9309
  term vulnerabilities
    doc 0
      freq 1
      pos 16708
    doc 2
      freq 2
      pos 2128
      pos 2180
    doc 18
      freq 1
      pos 1651
  term vulnerabl
    doc 0
      freq 1
      pos 16122
    doc 9
      freq 1
      pos 1507
    doc 18
      freq 2
      pos 1681
      pos 1705
  term vvadlxikjgilniuhqgcvqlq
    doc 11
      freq 1
      pos 10222
  term vvjpqnskziooqa2q0hfqioiugwwlyfsgxcgoxaqzfml7wvcfaaa7vv9phhh
    doc 11
      freq 1
      pos 10177
  term vvnw1vcwz
    doc 11
      freq 1
      pos 10087
  term vwjvuqosof
    doc 11
      freq 1
      pos 9908
  term vx
    doc 11
      freq 1
      pos 10093
  term vxvpbokzsfg8ittsc5ppaudadov
    doc 11
      freq 1
      pos 10032
  term vyjecqqccs1lkgexonqpqonalvyhyymzrxfldd4gbwrpk1uxk
    doc 10
      freq 1
      pos 6240
  term vzmwfkdu4hadzesmr
    doc 11
      freq 1
      pos 10404
  term vzuir0zvikef0djs
    doc 11
      freq 1
      pos 10348
  term w
    doc 1
      freq 1
      pos 9237
    doc 2
      freq 3
      pos 2850
      pos 3024
      pos 3093
    doc 3
      freq 1
      pos 4631
    doc 4
      freq 1
      pos 5199
    doc 8
      freq 1
      pos 2082
    doc 10
      freq 2
      pos 13230
      pos 13232
    doc 11
      freq 3
      pos 10088
      pos 10290
      pos 10487
    doc 15
      freq 1
      pos 3927
    doc 16
      freq 1
      pos 2651
    doc 17
      freq 2
      pos 2050
      pos 2052
    skipList 
      level 0
        skipDoc 15
        skipDocFP 2605509
        impacts 
          impact 
            freq 1
            norm 97
          impact 
            freq 3
            norm 108
        impactsEnd 
  term w1tysgjs2fax
    doc 10
      freq 1
      pos 6889
  term w2cuo8
    doc 11
      freq 1
      pos 10132
  term w3
    doc 14
      freq 1
      pos 5533
  term w6ouf
    doc 11
      freq 1
      pos 10309
  term w7ax3
    doc 11
      freq 1
      pos 10332
  term w7oecjarzhgwazq04ltgujcpiwkuq
    doc 10
      freq 1
      pos 12796
  term w8
    doc 11
      freq 2
      pos 10382
      pos 10461
  term w8syyheeygp0liecwj0gkskmax
    doc 11
      freq 1
      pos 9881
  term wa
    doc 2
      freq 1
      pos 6383
  term wait
    doc 0
      freq 1
      pos 13026
    doc 1
      freq 4
      pos 6858
      pos 6947
      pos 7626
      pos 9476
    doc 2
      freq 1
      pos 4401
    doc 11
      freq 1
      pos 4423
  term waiting
    doc 0
      freq 4
      pos 1651
      pos 2681
      pos 4912
      pos 4943
    doc 12
      freq 1
      pos 3555
  term waitingtim
    doc 0
      freq 1
      pos 2702
  term waits
    doc 1
      freq 1
      pos 7071
  term waiving
    doc 2
      freq 1
      pos 1921
  term wake
    doc 13
      freq 1
      pos 4132
  term walk
    doc 0
      freq 1
      pos 9522
  term walker
    doc 2
      freq 1
      pos 3286
  term walking
    doc 18
      freq 8
      pos 139
      pos 274
      pos 306
      pos 320
      pos 338
      pos 442
      pos 528
      pos 1795
  term walsh
    doc 13
      freq 3
      pos 14
      pos 6857
      pos 7008
  term wan
    doc 2
      freq 3
      pos 269
      pos 3256
      pos 3998
    doc 7
      freq 2
      pos 1009
      pos 2496
    doc 10
      freq 1
      pos 12171
  term want
    doc 5
      freq 2
      pos 3290
      pos 3316
    doc 11
      freq 1
      pos 9172
    doc 13
      freq 1
      pos 4905
    doc 15
      freq 2
      pos 2421
      pos 2698
    doc 18
      freq 1
      pos 958
  term wanting
    doc 12
      freq 1
      pos 2255
  term wants
    doc 1
      freq 1
      pos 7678
    doc 10
      freq 3
      pos 1813
      pos 6292
      pos 6920
    doc 13
      freq 1
      pos 3393
    doc 18
      freq 1
      pos 428
  term warn
    doc 12
      freq 1
      pos 9394
  term warner
    doc 6
      freq 1
      pos 3111
  term warning
    doc 11
      freq 4
      pos 4997
      pos 5001
      pos 5054
      pos 9018
    doc 12
      freq 1
      pos 9373
  term warnings
    doc 10
      freq 1
      pos 6108
  term warranties
    doc 0
      freq 2
      pos 17297
      pos 17323
    doc 1
      freq 2
      pos 9678
      pos 9704
    doc 2
      freq 2
      pos 6475
      pos 6501
    doc 3
      freq 2
      pos 6027
      pos 6053
    doc 4
      freq 2
      pos 6182
      pos 6208
    doc 5
      freq 2
      pos 4512
      pos 4538
    doc 6
      freq 2
      pos 3312
      pos 3338
    doc 7
      freq 2
      pos 3017
      pos 3043
    doc 8
      freq 2
      pos 2234
      pos 2260
    doc 9
      freq 2
      pos 1879
      pos 1905
    doc 10
      freq 2
      pos 13540
      pos 13566
    doc 11
      freq 2
      pos 10701
      pos 10727
    doc 12
      freq 2
      pos 9551
      pos 9577
    doc 13
      freq 2
      pos 7166
      pos 7192
    doc 14
      freq 2
      pos 5632
      pos 5658
    doc 15
      freq 2
      pos 4151
      pos 4177
    doc 16
      freq 2
      pos 2762
      pos 2788
    doc 17
      freq 2
      pos 2486
      pos 2512
    doc 18
      freq 2
      pos 2274
      pos 2300
    skipList 
      level 0
        skipDoc 7
        skipDocFP 2608610
        impacts 
          impact 
            freq 2
            norm 100
        impactsEnd 
        skipDoc 15
        skipDocFP 2609036
        impacts 
          impact 
            freq 2
            norm 95
        impactsEnd 
  term warranty
    doc 0
      freq 1
      pos 17307
    doc 1
      freq 1
      pos 9688
    doc 2
      freq 1
      pos 6485
    doc 3
      freq 1
      pos 6037
    doc 4
      freq 1
      pos 6192
    doc 5
      freq 1
      pos 4522
    doc 6
      freq 1
      pos 3322
    doc 7
      freq 1
      pos 3027
    doc 8
      freq 1
      pos 2244
    doc 9
      freq 1
      pos 1889
    doc 10
      freq 1
      pos 13550
    doc 11
      freq 1
      pos 10711
    doc 12
      freq 1
      pos 9561
    doc 13
      freq 1
      pos 7176
    doc 14
      freq 1
      pos 5642
    doc 15
      freq 1
      pos 4161
    doc 16
      freq 1
      pos 2772
    doc 17
      freq 1
      pos 2496
    doc 18
      freq 1
      pos 2284
    skipList 
      level 0
        skipDoc 7
        skipDocFP 2609954
        impacts 
          impact 
            freq 1
            norm 100
        impactsEnd 
        skipDoc 15
        skipDocFP 2610259
        impacts 
          impact 
            freq 1
            norm 95
        impactsEnd 
  term was
    doc 0
      freq 5
      pos 2162
      pos 2172
      pos 2262
      pos 4577
      pos 12938
    doc 1
      freq 8
      pos 1363
      pos 1425
      pos 5946
      pos 6804
      pos 6841
      pos 6881
      pos 8162
      pos 8274
    doc 2
      freq 60
      pos 828
      pos 1762
      pos 3560
      pos 3678
      pos 3685
      pos 3976
      pos 4024
      pos 4037
      pos 4124
      pos 4150
      pos 4186
      pos 4243
      pos 4268
      pos 4323
      pos 4341
      pos 4383
      pos 4406
      pos 4427
      pos 4461
      pos 4501
      pos 4554
      pos 4588
      pos 4612
      pos 4625
      pos 4638
      pos 4699
      pos 4716
      pos 4769
      pos 4918
      pos 4951
      pos 5053
      pos 5093
      pos 5157
      pos 5165
      pos 5192
      pos 5208
      pos 5258
      pos 5325
      pos 5489
      pos 5504
      pos 5555
      pos 5612
      pos 5634
      pos 5772
      pos 5783
      pos 5798
      pos 5870
      pos 5878
      pos 5913
      pos 5927
      pos 5937
      pos 5953
      pos 6011
      pos 6043
      pos 6068
      pos 6125
      pos 6153
      pos 6185
      pos 6227
      pos 6291
    doc 3
      freq 2
      pos 2360
      pos 2448
    doc 4
      freq 5
      pos 3343
      pos 3468
      pos 3939
      pos 5079
      pos 5516
    doc 5
      freq 2
      pos 2572
      pos 3741
    doc 7
      freq 10
      pos 181
      pos 331
      pos 422
      pos 514
      pos 528
      pos 603
      pos 608
      pos 674
      pos 1142
      pos 1466
    doc 9
      freq 1
      pos 1492
    doc 10
      freq 3
      pos 2610
      pos 4302
      pos 10702
    doc 11
      freq 2
      pos 4376
      pos 9430
    doc 12
      freq 7
      pos 983
      pos 4459
      pos 4638
      pos 4842
      pos 6944
      pos 8739
      pos 8751
    doc 14
      freq 1
      pos 1092
    doc 15
      freq 3
      pos 323
      pos 1450
      pos 1508
    doc 16
      freq 5
      pos 314
      pos 2140
      pos 2151
      pos 2231
      pos 2505
    doc 17
      freq 2
      pos 1378
      pos 1967
    doc 18
      freq 3
      pos 513
      pos 519
      pos 839
    skipList 
      level 0
        skipDoc 9
        skipDocFP 2611005
        impacts 
          impact 
            freq 1
            norm 95
          impact 
            freq 10
            norm 100
          impact 
            freq 60
            norm 108
        impactsEnd 
        skipDoc 18
        skipDocFP 2612578
        impacts 
          impact 
            freq 3
            norm 97
          impact 
            freq 5
            norm 99
          impact 
            freq 7
            norm 113
        impactsEnd 
  term wasn't
    doc 11
      freq 1
      pos 6100
  term wasserman
    doc 15
      freq 1
      pos 3856
  term watson
    doc 10
      freq 2
      pos 12118
      pos 13293
    doc 11
      freq 3
      pos 6459
      pos 6620
      pos 6697
  term way
    doc 0
      freq 4
      pos 441
      pos 9167
      pos 9520
      pos 17154
    doc 1
      freq 2
      pos 8086
      pos 9303
    doc 2
      freq 2
      pos 1345
      pos 6381
    doc 3
      freq 3
      pos 1756
      pos 2210
      pos 3828
    doc 4
      freq 3
      pos 915
      pos 1232
      pos 4472
    doc 5
      freq 4
      pos 630
      pos 710
      pos 1218
      pos 1234
    doc 9
      freq 1
      pos 787
    doc 10
      freq 11
      pos 489
      pos 1219
      pos 1305
      pos 4036
      pos 4554
      pos 7731
      pos 8938
      pos 9302
      pos 9386
      pos 11096
      pos 11352
    doc 11
      freq 2
      pos 672
      pos 8358
    doc 12
      freq 5
      pos 1012
      pos 1191
      pos 4871
      pos 5288
      pos 5809
    doc 13
      freq 5
      pos 990
      pos 1969
      pos 5173
      pos 5296
      pos 5805
    doc 15
      freq 2
      pos 1299
      pos 2888
    doc 16
      freq 1
      pos 318
    doc 18
      freq 2
      pos 302
      pos 929
    skipList 
      level 0
        skipDoc 10
        skipDocFP 2613952
        impacts 
          impact 
            freq 1
            norm 95
          impact 
            freq 4
            norm 104
          impact 
            freq 11
            norm 116
        impactsEnd 
  term ways
    doc 7
      freq 1
      pos 1755
    doc 10
      freq 6
      pos 2563
      pos 4073
      pos 5895
      pos 8707
      pos 10438
      pos 11295
    doc 11
      freq 1
      pos 9356
    doc 12
      freq 3
      pos 1439
      pos 1858
      pos 2305
    doc 13
      freq 1
      pos 713
    doc 14
      freq 2
      pos 1188
      pos 2569
    doc 15
      freq 1
      pos 3206
  term wbssbyaptywfjtmijumjqqrwdmp1uh2jg4lctpnimxdesj
    doc 11
      freq 1
      pos 10366
  term wcemb
    doc 10
      freq 1
      pos 12628
  term wco5sudtwxxknvnegyrwiq5whatejxb0lxb6trgd2ds0zzsclwm6b
    doc 10
      freq 1
      pos 12487
  term wcwihz
    doc 11
      freq 1
      pos 10153
  term wdp
    doc 11
      freq 1
      pos 10344
  term wdsevcvqqqrwnuqpuvh
    doc 11
      freq 1
      pos 10039
  term we
    doc 0
      freq 57
      pos 679
      pos 1859
      pos 2826
      pos 2870
      pos 2907
      pos 4946
      pos 5154
      pos 5183
      pos 5209
      pos 5913
      pos 6089
      pos 7055
      pos 7066
      pos 7694
      pos 7714
      pos 7729
      pos 7882
      pos 8403
      pos 12002
      pos 12430
      pos 12456
      pos 12492
      pos 12516
      pos 12932
      pos 12957
      pos 12962
      pos 13015
      pos 13023
      pos 13044
      pos 13085
      pos 13108
      pos 13199
      pos 13288
      pos 13349
      pos 13360
      pos 13372
      pos 13377
      pos 13419
      pos 13505
      pos 13604
      pos 13694
      pos 13797
      pos 13871
      pos 14004
      pos 14264
      pos 14363
      pos 15898
      pos 16177
      pos 16196
      pos 16256
      pos 16361
      pos 16382
      pos 16420
      pos 16446
      pos 16523
      pos 16576
      pos 16581
    doc 1
      freq 13
      pos 728
      pos 752
      pos 775
      pos 805
      pos 1214
      pos 1228
      pos 1285
      pos 1316
      pos 1343
      pos 2142
      pos 3104
      pos 3139
      pos 7974
    doc 3
      freq 2
      pos 686
      pos 2344
    doc 5
      freq 1
      pos 4085
    doc 7
      freq 7
      pos 453
      pos 466
      pos 489
      pos 1274
      pos 1388
      pos 1429
      pos 1606
    doc 12
      freq 6
      pos 2869
      pos 2877
      pos 3649
      pos 4277
      pos 4942
      pos 8687
    doc 13
      freq 5
      pos 898
      pos 951
      pos 1525
      pos 1646
      pos 1863
    doc 15
      freq 10
      pos 503
      pos 530
      pos 820
      pos 1763
      pos 2420
      pos 2532
      pos 3512
      pos 3679
      pos 3681
      pos 3720
    skipList 
      level 0
        skipDoc 15
        skipDocFP 2616098
        impacts 
          impact 
            freq 7
            norm 100
          impact 
            freq 10
            norm 104
          impact 
            freq 13
            norm 113
          impact 
            freq 57
            norm 120
        impactsEnd 
  term we'll
    doc 12
      freq 1
      pos 8094
  term we5bp
    doc 11
      freq 1
      pos 10110
  term weak
    doc 10
      freq 2
      pos 10006
      pos 10362
    doc 12
      freq 4
      pos 4989
      pos 5377
      pos 6876
      pos 6954
    doc 17
      freq 1
      pos 1665
  term weaker
    doc 10
      freq 2
      pos 1417
      pos 9521
  term weakest
    doc 5
      freq 1
      pos 3219
  term weaknesses
    doc 2
      freq 1
      pos 2163
    doc 10
      freq 1
      pos 9548
  term web
    doc 2
      freq 1
      pos 493
    doc 4
      freq 1
      pos 4927
    doc 12
      freq 1
      pos 4982
    doc 13
      freq 6
      pos 469
      pos 640
      pos 777
      pos 1719
      pos 2500
      pos 2626
  term webcams
    doc 15
      freq 1
      pos 3362
  term websit
    doc 2
      freq 2
      pos 749
      pos 4100
  term websites
    doc 2
      freq 1
      pos 973
  term weed
    doc 12
      freq 1
      pos 5128
  term weeds
    doc 1
      freq 1
      pos 8890
  term week
    doc 10
      freq 1
      pos 5125
  term weekday
    doc 10
      freq 2
      pos 5066
      pos 5086
  term weeks
    doc 12
      freq 1
      pos 6650
  term wei
    doc 1
      freq 1
      pos 8884
  term weidemanns
    doc 7
      freq 1
      pos 2923
  term weiler
    doc 14
      freq 2
      pos 5344
      pos 5469
    doc 18
      freq 11
      pos 4
      pos 239
      pos 615
      pos 1023
      pos 1378
      pos 1805
      pos 2145
      pos 2160
      pos 2172
      pos 2188
      pos 2519
  term weird
    doc 11
      freq 1
      pos 1922
  term weisenberg
    doc 11
      freq 1
      pos 9589
  term welch
    doc 6
      freq 12
      pos 4
      pos 282
      pos 735
      pos 1125
      pos 1606
      pos 2021
      pos 2335
      pos 2751
      pos 3028
      pos 3181
      pos 3218
      pos 3557
  term welcom
    doc 2
      freq 1
      pos 5428
  term well
    doc 1
      freq 2
      pos 4194
      pos 8120
    doc 2
      freq 18
      pos 105
      pos 481
      pos 502
      pos 994
      pos 1046
      pos 4489
      pos 4785
      pos 4888
      pos 5004
      pos 5179
      pos 5205
      pos 5245
      pos 5567
      pos 5682
      pos 5978
      pos 6078
      pos 6147
      pos 6163
    doc 4
      freq 1
      pos 413
    doc 5
      freq 3
      pos 585
      pos 666
      pos 2133
    doc 6
      freq 5
      pos 109
      pos 381
      pos 933
      pos 2244
      pos 2258
    doc 9
      freq 1
      pos 200
    doc 10
      freq 5
      pos 544
      pos 1397
      pos 3060
      pos 5883
      pos 7103
    doc 11
      freq 16
      pos 1356
      pos 2125
      pos 2317
      pos 2438
      pos 2508
      pos 2669
      pos 2715
      pos 3486
      pos 3586
      pos 3732
      pos 3969
      pos 4083
      pos 7300
      pos 7446
      pos 7911
      pos 8398
    doc 12
      freq 9
      pos 2465
      pos 4111
      pos 4428
      pos 4917
      pos 5985
      pos 6281
      pos 6464
      pos 8167
      pos 8692
    doc 13
      freq 11
      pos 382
      pos 411
      pos 528
      pos 848
      pos 957
      pos 1704
      pos 1729
      pos 2244
      pos 5699
      pos 5746
      pos 6678
    doc 15
      freq 2
      pos 665
      pos 2763
    doc 16
      freq 1
      pos 1884
    doc 17
      freq 1
      pos 196
    doc 18
      freq 2
      pos 594
      pos 1672
    skipList 
      level 0
        skipDoc 11
        skipDocFP 2620111
        impacts 
          impact 
            freq 1
            norm 95
          impact 
            freq 5
            norm 101
          impact 
            freq 18
            norm 108
        impactsEnd 
  term wellington
    doc 12
      freq 1
      pos 7110
  term were
    doc 0
      freq 2
      pos 2267
      pos 8402
    doc 1
      freq 2
      pos 6484
      pos 8546
    doc 2
      freq 25
      pos 387
      pos 392
      pos 3619
      pos 3735
      pos 4009
      pos 4119
      pos 4166
      pos 4175
      pos 4352
      pos 4519
      pos 4543
      pos 4598
      pos 4680
      pos 4748
      pos 4757
      pos 5039
      pos 5062
      pos 5436
      pos 5460
      pos 5470
      pos 5479
      pos 5546
      pos 5606
      pos 6201
      pos 6287
    doc 3
      freq 1
      pos 2227
    doc 4
      freq 4
      pos 4660
      pos 5547
      pos 5574
      pos 5665
    doc 7
      freq 17
      pos 101
      pos 502
      pos 543
      pos 553
      pos 559
      pos 636
      pos 660
      pos 668
      pos 1202
      pos 1241
      pos 1249
      pos 1291
      pos 1335
      pos 1351
      pos 1389
      pos 1476
      pos 1793
    doc 9
      freq 2
      pos 1326
      pos 1361
    doc 10
      freq 4
      pos 5649
      pos 7093
      pos 8729
      pos 12844
    doc 11
      freq 12
      pos 610
      pos 1298
      pos 1370
      pos 4107
      pos 4814
      pos 4829
      pos 4836
      pos 6077
      pos 6553
      pos 7974
      pos 8595
      pos 9462
    doc 12
      freq 4
      pos 6093
      pos 6120
      pos 6757
      pos 8490
    doc 13
      freq 1
      pos 2609
    doc 14
      freq 1
      pos 1926
    doc 15
      freq 2
      pos 810
      pos 2933
    doc 16
      freq 2
      pos 790
      pos 2481
    skipList 
      level 0
        skipDoc 10
        skipDocFP 2621932
        impacts 
          impact 
            freq 2
            norm 95
          impact 
            freq 17
            norm 100
          impact 
            freq 25
            norm 108
        impactsEnd 
  term west
    doc 4
      freq 1
      pos 6064
    doc 10
      freq 1
      pos 13434
    doc 14
      freq 1
      pos 5514
  term westerlund
    doc 13
      freq 1
      pos 6977
  term wg
    doc 0
      freq 1
      pos 1103
    doc 2
      freq 55
      pos 673
      pos 863
      pos 885
      pos 891
      pos 906
      pos 920
      pos 939
      pos 991
      pos 1032
      pos 1088
      pos 1215
      pos 1447
      pos 1758
      pos 1798
      pos 2030
      pos 2274
      pos 2836
      pos 2840
      pos 3548
      pos 3577
      pos 3652
      pos 3744
      pos 3772
      pos 3780
      pos 3852
      pos 3882
      pos 3985
      pos 3988
      pos 4018
      pos 4033
      pos 4056
      pos 4219
      pos 4287
      pos 4405
      pos 4593
      pos 4636
      pos 4743
      pos 5163
      pos 5191
      pos 5230
      pos 5264
      pos 5271
      pos 5335
      pos 5346
      pos 5441
      pos 5475
      pos 5627
      pos 5685
      pos 5790
      pos 5833
      pos 5875
      pos 5901
      pos 5926
      pos 6238
      pos 6241
    doc 12
      freq 1
      pos 6821
    doc 15
      freq 3
      pos 1775
      pos 3601
      pos 3793
  term wgly6ljqtzwsd2zhagom
    doc 11
      freq 1
      pos 10495
  term wgs
    doc 2
      freq 15
      pos 717
      pos 723
      pos 785
      pos 820
      pos 851
      pos 873
      pos 1228
      pos 1481
      pos 1518
      pos 1525
      pos 4364
      pos 4914
      pos 5400
      pos 6030
      pos 6234
    doc 15
      freq 1
      pos 3782
  term wgt
    doc 10
      freq 1
      pos 12481
  term what
    doc 0
      freq 1
      pos 7852
    doc 1
      freq 3
      pos 508
      pos 6447
      pos 6771
    doc 4
      freq 1
      pos 3363
    doc 7
      freq 3
      pos 1471
      pos 1747
      pos 1754
    doc 10
      freq 1
      pos 8092
    doc 11
      freq 10
      pos 658
      pos 2041
      pos 2520
      pos 5283
      pos 5583
      pos 5749
      pos 5882
      pos 6090
      pos 6319
      pos 6542
    doc 12
      freq 4
      pos 607
      pos 943
      pos 6180
      pos 6943
    doc 13
      freq 1
      pos 2760
    doc 15
      freq 3
      pos 1437
      pos 2380
      pos 2727
    skipList 
      level 0
        skipDoc 13
        skipDocFP 2625329
        impacts 
          impact 
            freq 3
            norm 100
          impact 
            freq 4
            norm 113
          impact 
            freq 10
            norm 114
        impactsEnd 
  term what's
    doc 12
      freq 1
      pos 3698
  term whatever
    doc 14
      freq 1
      pos 2016
    doc 15
      freq 1
      pos 2962
  term whelan
    doc 13
      freq 1
      pos 6778
  term when
    doc 0
      freq 66
      pos 127
      pos 325
      pos 565
      pos 944
      pos 970
      pos 1140
      pos 2165
      pos 2355
      pos 2498
      pos 2638
      pos 2746
      pos 3282
      pos 3304
      pos 3815
      pos 3911
      pos 4041
      pos 4064
      pos 4315
      pos 4423
      pos 4785
      pos 5063
      pos 5083
      pos 5121
      pos 5529
      pos 5707
      pos 6952
      pos 8957
      pos 9329
      pos 10142
      pos 10728
      pos 11179
      pos 11261
      pos 11441
      pos 12799
      pos 12838
      pos 12850
      pos 12901
      pos 12931
      pos 13008
      pos 13084
      pos 13155
      pos 13198
      pos 13257
      pos 13287
      pos 13348
      pos 13418
      pos 13474
      pos 13504
      pos 13572
      pos 13603
      pos 13664
      pos 13693
      pos 13766
      pos 13796
      pos 13839
      pos 13870
      pos 13911
      pos 13955
      pos 13976
      pos 14019
      pos 14051
      pos 14083
      pos 14180
      pos 14211
      pos 14263
      pos 14766
    doc 1
      freq 25
      pos 494
      pos 1394
      pos 1408
      pos 1473
      pos 1716
      pos 2154
      pos 3896
      pos 3954
      pos 3967
      pos 4274
      pos 4414
      pos 5195
      pos 5363
      pos 5608
      pos 5977
      pos 6123
      pos 6316
      pos 7388
      pos 7466
      pos 7659
      pos 7712
      pos 8031
      pos 8216
      pos 8738
      pos 8751
    doc 2
      freq 2
      pos 3675
      pos 4729
    doc 3
      freq 13
      pos 1946
      pos 2128
      pos 2275
      pos 2330
      pos 2507
      pos 2697
      pos 2732
      pos 3709
      pos 3801
      pos 3850
      pos 5218
      pos 5419
      pos 5661
    doc 4
      freq 7
      pos 1353
      pos 1854
      pos 2393
      pos 2410
      pos 2920
      pos 4901
      pos 5633
    doc 5
      freq 1
      pos 903
    doc 6
      freq 2
      pos 1709
      pos 1975
    doc 7
      freq 2
      pos 937
      pos 1751
    doc 8
      freq 1
      pos 457
    doc 9
      freq 5
      pos 734
      pos 745
      pos 943
      pos 1291
      pos 1421
    doc 10
      freq 35
      pos 1102
      pos 2020
      pos 2313
      pos 3259
      pos 3466
      pos 3483
      pos 3508
      pos 3737
      pos 3807
      pos 4414
      pos 4660
      pos 5111
      pos 5486
      pos 5679
      pos 6001
      pos 6035
      pos 6405
      pos 6711
      pos 7009
      pos 7568
      pos 8172
      pos 9144
      pos 10024
      pos 10072
      pos 10137
      pos 10288
      pos 10312
      pos 10368
      pos 10597
      pos 11189
      pos 11240
      pos 11572
      pos 11660
      pos 11754
      pos 11867
    doc 11
      freq 13
      pos 166
      pos 2329
      pos 2407
      pos 2658
      pos 4368
      pos 5137
      pos 5592
      pos 5758
      pos 7051
      pos 7586
      pos 7810
      pos 7918
      pos 8404
    doc 12
      freq 34
      pos 280
      pos 1533
      pos 1749
      pos 1958
      pos 2254
      pos 2306
      pos 2391
      pos 2496
      pos 2517
      pos 2788
      pos 2806
      pos 2900
      pos 2978
      pos 3004
      pos 3224
      pos 3271
      pos 3316
      pos 3342
      pos 3451
      pos 3605
      pos 3771
      pos 3792
      pos 3861
      pos 3880
      pos 4024
      pos 4781
      pos 5593
      pos 6069
      pos 6974
      pos 8100
      pos 8427
      pos 8461
      pos 8823
      pos 9374
    doc 13
      freq 10
      pos 785
      pos 2864
      pos 3389
      pos 3475
      pos 4227
      pos 4359
      pos 4362
      pos 4443
      pos 4823
      pos 5613
    doc 14
      freq 4
      pos 1911
      pos 1942
      pos 2217
      pos 2469
    doc 15
      freq 2
      pos 1498
      pos 2497
    doc 16
      freq 3
      pos 946
      pos 1091
      pos 1229
    doc 17
      freq 7
      pos 121
      pos 164
      pos 414
      pos 761
      pos 951
      pos 1071
      pos 1366
    doc 18
      freq 1
      pos 873
    skipList 
      level 0
        skipDoc 7
        skipDocFP 2626440
        impacts 
          impact 
            freq 2
            norm 100
          impact 
            freq 13
            norm 107
          impact 
            freq 25
            norm 113
          impact 
            freq 66
            norm 120
        impactsEnd 
        skipDoc 15
        skipDocFP 2628427
        impacts 
          impact 
            freq 5
            norm 95
          impact 
            freq 10
            norm 109
          impact 
            freq 34
            norm 113
          impact 
            freq 35
            norm 116
        impactsEnd 
  term whenever
    doc 1
      freq 1
      pos 2398
    doc 10
      freq 2
      pos 7648
      pos 10245
    doc 18
      freq 3
      pos 606
      pos 719
      pos 740
  term where
    doc 0
      freq 2
      pos 6596
      pos 13107
    doc 1
      freq 8
      pos 1920
      pos 2959
      pos 3220
      pos 4783
      pos 7368
      pos 7510
      pos 7674
      pos 8431
    doc 2
      freq 7
      pos 1047
      pos 1146
      pos 1328
      pos 1494
      pos 1596
      pos 1602
      pos 5394
    doc 3
      freq 1
      pos 3432
    doc 4
      freq 9
      pos 1406
      pos 1471
      pos 1524
      pos 1905
      pos 2000
      pos 3340
      pos 3465
      pos 4932
      pos 5567
    doc 5
      freq 4
      pos 170
      pos 699
      pos 2428
      pos 2514
    doc 6
      freq 4
      pos 1739
      pos 1751
      pos 2060
      pos 2173
    doc 7
      freq 1
      pos 1247
    doc 8
      freq 1
      pos 948
    doc 9
      freq 4
      pos 323
      pos 391
      pos 614
      pos 1518
    doc 10
      freq 11
      pos 464
      pos 1129
      pos 1797
      pos 5785
      pos 5815
      pos 6589
      pos 7305
      pos 10270
      pos 10351
      pos 10454
      pos 10728
    doc 11
      freq 6
      pos 986
      pos 2160
      pos 5442
      pos 8661
      pos 8775
      pos 8880
    doc 12
      freq 18
      pos 1022
      pos 1098
      pos 2080
      pos 2244
      pos 2995
      pos 3692
      pos 3969
      pos 4048
      pos 4699
      pos 5557
      pos 5884
      pos 6165
      pos 6187
      pos 6194
      pos 6213
      pos 6264
      pos 6889
      pos 8397
    doc 13
      freq 7
      pos 739
      pos 2504
      pos 2683
      pos 3522
      pos 4098
      pos 4511
      pos 4533
    doc 14
      freq 24
      pos 510
      pos 1135
      pos 2627
      pos 2720
      pos 2778
      pos 2796
      pos 3218
      pos 3229
      pos 3267
      pos 3551
      pos 3824
      pos 3849
      pos 4161
      pos 4231
      pos 4296
      pos 4418
      pos 4512
      pos 4594
      pos 4972
      pos 4988
      pos 5011
      pos 5027
      pos 5145
      pos 5163
    doc 15
      freq 12
      pos 877
      pos 1632
      pos 1794
      pos 1967
      pos 2027
      pos 2051
      pos 2164
      pos 2169
      pos 2614
      pos 3574
      pos 3712
      pos 3746
    doc 16
      freq 3
      pos 445
      pos 925
      pos 960
    skipList 
      level 0
        skipDoc 7
        skipDocFP 2631265
        impacts 
          impact 
            freq 1
            norm 100
          impact 
            freq 4
            norm 101
          impact 
            freq 9
            norm 108
        impactsEnd 
        skipDoc 15
        skipDocFP 2631988
        impacts 
          impact 
            freq 4
            norm 95
          impact 
            freq 12
            norm 104
          impact 
            freq 24
            norm 107
        impactsEnd 
  term whereas
    doc 2
      freq 1
      pos 5731
    doc 13
      freq 1
      pos 5256
    doc 15
      freq 1
      pos 2064
  term whereby
    doc 5
      freq 1
      pos 3177
    doc 12
      freq 1
      pos 8834
  term whether
    doc 0
      freq 3
      pos 555
      pos 10515
      pos 11541
    doc 1
      freq 2
      pos 4656
      pos 6418
    doc 3
      freq 3
      pos 2466
      pos 3374
      pos 3578
    doc 5
      freq 1
      pos 3383
    doc 6
      freq 1
      pos 474
    doc 7
      freq 3
      pos 184
      pos 566
      pos 1222
    doc 8
      freq 1
      pos 293
    doc 10
      freq 6
      pos 801
      pos 1015
      pos 2451
      pos 2527
      pos 11215
      pos 11280
    doc 12
      freq 11
      pos 966
      pos 1304
      pos 2070
      pos 3292
      pos 3422
      pos 4635
      pos 4999
      pos 5179
      pos 5462
      pos 8189
      pos 8702
    doc 13
      freq 1
      pos 4791
    doc 14
      freq 1
      pos 1795
    doc 15
      freq 15
      pos 720
      pos 752
      pos 768
      pos 905
      pos 913
      pos 1223
      pos 1934
      pos 2372
      pos 2830
      pos 3091
      pos 3305
      pos 3318
      pos 3471
      pos 3499
      pos 3544
    doc 17
      freq 3
      pos 128
      pos 399
      pos 745
    doc 18
      freq 1
      pos 1604
    skipList 
      level 0
        skipDoc 10
        skipDocFP 2634266
        impacts 
          impact 
            freq 1
            norm 97
          impact 
            freq 3
            norm 100
          impact 
            freq 6
            norm 116
        impactsEnd 
  term which
    doc 0
      freq 33
      pos 279
      pos 503
      pos 1525
      pos 2200
      pos 2342
      pos 2485
      pos 3061
      pos 3092
      pos 4570
      pos 5149
      pos 5178
      pos 5608
      pos 5836
      pos 8377
      pos 9703
      pos 10552
      pos 10639
      pos 10764
      pos 11608
      pos 11809
      pos 13118
      pos 13220
      pos 13312
      pos 13437
      pos 13523
      pos 13627
      pos 13717
      pos 14281
      pos 14422
      pos 14588
      pos 16005
      pos 16673
      pos 17374
    doc 1
      freq 19
      pos 325
      pos 336
      pos 518
      pos 606
      pos 763
      pos 873
      pos 1359
      pos 3188
      pos 4364
      pos 5173
      pos 5203
      pos 5864
      pos 6292
      pos 6375
      pos 6398
      pos 6470
      pos 6697
      pos 8169
      pos 9755
    doc 2
      freq 15
      pos 406
      pos 675
      pos 849
      pos 3559
      pos 3712
      pos 3745
      pos 3931
      pos 3953
      pos 4238
      pos 4856
      pos 4968
      pos 5139
      pos 5164
      pos 5971
      pos 6552
    doc 3
      freq 9
      pos 676
      pos 835
      pos 1493
      pos 2171
      pos 2212
      pos 2401
      pos 3352
      pos 4280
      pos 6104
    doc 4
      freq 11
      pos 1605
      pos 2495
      pos 2576
      pos 3934
      pos 4713
      pos 4735
      pos 4955
      pos 5078
      pos 5663
      pos 5753
      pos 6259
    doc 5
      freq 11
      pos 1155
      pos 1285
      pos 1384
      pos 1397
      pos 1417
      pos 1444
      pos 1463
      pos 1994
      pos 2287
      pos 3670
      pos 4589
    doc 6
      freq 8
      pos 79
      pos 1254
      pos 1507
      pos 1768
      pos 1952
      pos 2490
      pos 2693
      pos 3389
    doc 7
      freq 3
      pos 243
      pos 1350
      pos 3094
    doc 8
      freq 1
      pos 2311
    doc 9
      freq 4
      pos 694
      pos 998
      pos 1402
      pos 1956
    doc 10
      freq 61
      pos 600
      pos 758
      pos 871
      pos 888
      pos 917
      pos 957
      pos 1048
      pos 1175
      pos 1265
      pos 1277
      pos 1286
      pos 1355
      pos 1366
      pos 1407
      pos 1443
      pos 2408
      pos 2431
      pos 2565
      pos 2609
      pos 2642
      pos 2750
      pos 2795
      pos 2891
      pos 3347
      pos 4373
      pos 4955
      pos 4960
      pos 5578
      pos 6307
      pos 6459
      pos 6946
      pos 7209
      pos 7518
      pos 7573
      pos 7734
      pos 8047
      pos 8419
      pos 8450
      pos 8872
      pos 8925
      pos 8943
      pos 9410
      pos 9524
      pos 9628
      pos 9900
      pos 10888
      pos 11297
      pos 11508
      pos 11563
      pos 11608
      pos 11651
      pos 11703
      pos 11745
      pos 11804
      pos 11858
      pos 11898
      pos 11956
      pos 11984
      pos 12039
      pos 12069
      pos 13617
    doc 11
      freq 6
      pos 2089
      pos 3218
      pos 3235
      pos 6287
      pos 7725
      pos 10778
    doc 12
      freq 16
      pos 477
      pos 721
      pos 981
      pos 1607
      pos 2251
      pos 2383
      pos 2664
      pos 2701
      pos 3593
      pos 3799
      pos 4595
      pos 6508
      pos 8181
      pos 8501
      pos 8644
      pos 9628
    doc 13
      freq 8
      pos 1963
      pos 2332
      pos 2386
      pos 5059
      pos 5095
      pos 5228
      pos 5344
      pos 7243
    doc 14
      freq 5
      pos 436
      pos 468
      pos 541
      pos 650
      pos 5709
    doc 15
      freq 16
      pos 144
      pos 885
      pos 1160
      pos 1165
      pos 1178
      pos 1194
      pos 1245
      pos 1260
      pos 1605
      pos 2116
      pos 2211
      pos 2367
      pos 2425
      pos 2955
      pos 3292
      pos 4228
    doc 16
      freq 4
      pos 707
      pos 735
      pos 1137
      pos 2839
    doc 17
      freq 4
      pos 209
      pos 608
      pos 1879
      pos 2563
    doc 18
      freq 3
      pos 351
      pos 584
      pos 2351
    skipList 
      level 0
        skipDoc 7
        skipDocFP 2635662
        impacts 
          impact 
            freq 3
            norm 100
          impact 
            freq 8
            norm 101
          impact 
            freq 11
            norm 104
          impact 
            freq 15
            norm 108
          impact 
            freq 19
            norm 113
          impact 
            freq 33
            norm 120
        impactsEnd 
        skipDoc 15
        skipDocFP 2637488
        impacts 
          impact 
            freq 4
            norm 95
          impact 
            freq 16
            norm 104
          impact 
            freq 61
            norm 116
        impactsEnd 
  term whichever
    doc 0
      freq 1
      pos 2194
    doc 12
      freq 1
      pos 9182
  term while
    doc 0
      freq 5
      pos 2139
      pos 2234
      pos 2439
      pos 11999
      pos 13052
    doc 1
      freq 3
      pos 668
      pos 7300
      pos 8355
    doc 2
      freq 8
      pos 778
      pos 1297
      pos 1313
      pos 1684
      pos 1902
      pos 4621
      pos 4788
      pos 5539
    doc 3
      freq 2
      pos 1290
      pos 1335
    doc 4
      freq 2
      pos 4531
      pos 4662
    doc 5
      freq 1
      pos 874
    doc 6
      freq 1
      pos 559
    doc 10
      freq 8
      pos 1394
      pos 8238
      pos 9165
      pos 10413
      pos 10764
      pos 11091
      pos 12401
      pos 13059
    doc 11
      freq 2
      pos 6135
      pos 9806
    doc 12
      freq 8
      pos 1716
      pos 3554
      pos 4209
      pos 4610
      pos 4893
      pos 5448
      pos 6678
      pos 8541
    doc 13
      freq 4
      pos 4109
      pos 4834
      pos 6147
      pos 6186
    doc 14
      freq 1
      pos 1887
    doc 15
      freq 9
      pos 384
      pos 493
      pos 651
      pos 697
      pos 1487
      pos 1689
      pos 2437
      pos 3251
      pos 3355
    doc 16
      freq 1
      pos 437
    doc 17
      freq 2
      pos 1597
      pos 1920
    skipList 
      level 0
        skipDoc 10
        skipDocFP 2640492
        impacts 
          impact 
            freq 1
            norm 101
          impact 
            freq 2
            norm 107
          impact 
            freq 8
            norm 108
        impactsEnd 
  term white
    doc 12
      freq 1
      pos 2717
  term whitelist
    doc 10
      freq 1
      pos 798
  term whitespac
    doc 10
      freq 2
      pos 5004
      pos 5192
    doc 11
      freq 2
      pos 921
      pos 928
  term who
    doc 0
      freq 3
      pos 15851
      pos 16680
      pos 16777
    doc 2
      freq 3
      pos 947
      pos 3608
      pos 3908
    doc 5
      freq 1
      pos 3409
    doc 9
      freq 3
      pos 579
      pos 587
      pos 1627
    doc 10
      freq 4
      pos 1799
      pos 9290
      pos 9312
      pos 9716
    doc 12
      freq 1
      pos 139
    doc 13
      freq 2
      pos 680
      pos 692
  term whois
    doc 7
      freq 7
      pos 1107
      pos 1120
      pos 1130
      pos 1211
      pos 2755
      pos 2779
      pos 2789
  term whole
    doc 1
      freq 1
      pos 8869
    doc 11
      freq 1
      pos 9577
    doc 12
      freq 3
      pos 4313
      pos 5400
      pos 8329
    doc 13
      freq 1
      pos 1793
  term whom
    doc 10
      freq 2
      pos 621
      pos 11786
  term whose
    doc 1
      freq 2
      pos 4434
      pos 8387
    doc 3
      freq 2
      pos 2264
      pos 2877
    doc 4
      freq 1
      pos 1786
    doc 10
      freq 3
      pos 3519
      pos 4298
      pos 10560
    doc 11
      freq 3
      pos 1722
      pos 1731
      pos 3473
    doc 12
      freq 2
      pos 2453
      pos 9204
  term why
    doc 10
      freq 2
      pos 5296
      pos 7829
  term wide
    doc 0
      freq 14
      pos 460
      pos 567
      pos 1275
      pos 1754
      pos 1866
      pos 1879
      pos 3964
      pos 4043
      pos 6452
      pos 7197
      pos 7214
      pos 7235
      pos 11571
      pos 16357
    doc 4
      freq 1
      pos 866
    doc 6
      freq 2
      pos 729
      pos 765
    doc 10
      freq 1
      pos 1005
    doc 11
      freq 2
      pos 143
      pos 1581
    doc 12
      freq 1
      pos 4339
    doc 13
      freq 5
      pos 1069
      pos 1798
      pos 2724
      pos 2741
      pos 5251
  term widely
    doc 12
      freq 1
      pos 2102
    doc 13
      freq 1
      pos 1715
  term wider
    doc 2
      freq 2
      pos 1220
      pos 2100
    doc 7
      freq 1
      pos 628
    doc 11
      freq 1
      pos 1590
    doc 13
      freq 1
      pos 1610
  term widespread
    doc 10
      freq 1
      pos 1527
  term wijnen
    doc 0
      freq 2
      pos 15972
      pos 17021
    doc 2
      freq 2
      pos 361
      pos 2436
  term wild
    doc 1
      freq 10
      pos 2710
      pos 2716
      pos 4176
      pos 4181
      pos 4253
      pos 4265
      pos 5384
      pos 5576
      pos 7259
      pos 7332
    doc 14
      freq 2
      pos 185
      pos 2223
  term wildcard
    doc 1
      freq 1
      pos 4284
    doc 12
      freq 3
      pos 5297
      pos 5341
      pos 6345
    doc 14
      freq 4
      pos 2176
      pos 2241
      pos 2260
      pos 2307
    doc 18
      freq 4
      pos 922
      pos 938
      pos 1007
      pos 1551
  term wiley
    doc 6
      freq 1
      pos 3004
  term wiljakk
    doc 12
      freq 1
      pos 7590
  term will
    doc 0
      freq 24
      pos 941
      pos 2908
      pos 3645
      pos 4161
      pos 5279
      pos 5348
      pos 5684
      pos 5840
      pos 5851
      pos 5858
      pos 5882
      pos 5997
      pos 6049
      pos 6572
      pos 6894
      pos 9206
      pos 11003
      pos 11755
      pos 12094
      pos 12982
      pos 13401
      pos 16067
      pos 16304
      pos 17315
    doc 1
      freq 31
      pos 474
      pos 547
      pos 1119
      pos 1136
      pos 1349
      pos 1401
      pos 1573
      pos 1668
      pos 1803
      pos 2069
      pos 2173
      pos 3329
      pos 3445
      pos 4223
      pos 4665
      pos 4981
      pos 5664
      pos 5804
      pos 5831
      pos 5850
      pos 5899
      pos 5909
      pos 6164
      pos 6353
      pos 7008
      pos 7033
      pos 7577
      pos 8255
      pos 8310
      pos 8352
      pos 9696
    doc 2
      freq 5
      pos 640
      pos 893
      pos 941
      pos 1919
      pos 6493
    doc 3
      freq 12
      pos 775
      pos 792
      pos 939
      pos 1701
      pos 1849
      pos 1909
      pos 2992
      pos 3067
      pos 3582
      pos 4103
      pos 5612
      pos 6045
    doc 4
      freq 9
      pos 857
      pos 3347
      pos 4308
      pos 4454
      pos 4869
      pos 4898
      pos 4915
      pos 4942
      pos 6200
    doc 5
      freq 5
      pos 1387
      pos 1401
      pos 1420
      pos 3111
      pos 4530
    doc 6
      freq 5
      pos 1283
      pos 1290
      pos 1428
      pos 2543
      pos 3330
    doc 7
      freq 3
      pos 351
      pos 454
      pos 3035
    doc 8
      freq 1
      pos 2252
    doc 9
      freq 4
      pos 436
      pos 1116
      pos 1442
      pos 1897
    doc 10
      freq 32
      pos 1767
      pos 2167
      pos 2367
      pos 3175
      pos 4521
      pos 5189
      pos 5271
      pos 5277
      pos 6463
      pos 6570
      pos 6583
      pos 7075
      pos 7167
      pos 7196
      pos 7213
      pos 7288
      pos 7299
      pos 7665
      pos 7903
      pos 8123
      pos 8271
      pos 8609
      pos 8632
      pos 9179
      pos 9694
      pos 10132
      pos 10265
      pos 10653
      pos 10865
      pos 10925
      pos 11063
      pos 13558
    doc 11
      freq 23
      pos 918
      pos 934
      pos 1105
      pos 1175
      pos 1802
      pos 1863
      pos 1871
      pos 1876
      pos 2655
      pos 3481
      pos 3492
      pos 5013
      pos 6753
      pos 7196
      pos 7309
      pos 7453
      pos 7695
      pos 7923
      pos 7939
      pos 7960
      pos 7986
      pos 8009
      pos 10719
    doc 12
      freq 14
      pos 1806
      pos 2503
      pos 3677
      pos 3794
      pos 4546
      pos 4701
      pos 4720
      pos 5685
      pos 6366
      pos 8471
      pos 8782
      pos 8788
      pos 9302
      pos 9569
    doc 13
      freq 15
      pos 1532
      pos 2734
      pos 3592
      pos 3793
      pos 3999
      pos 4241
      pos 4629
      pos 5165
      pos 5206
      pos 5262
      pos 5291
      pos 5455
      pos 5471
      pos 5557
      pos 7184
    doc 14
      freq 9
      pos 1087
      pos 1725
      pos 1844
      pos 2050
      pos 2293
      pos 2310
      pos 2424
      pos 2454
      pos 5650
    doc 15
      freq 13
      pos 434
      pos 604
      pos 657
      pos 1929
      pos 1977
      pos 2097
      pos 2172
      pos 2408
      pos 2426
      pos 2772
      pos 3349
      pos 3384
      pos 4169
    doc 16
      freq 3
      pos 1192
      pos 1333
      pos 2780
    doc 17
      freq 8
      pos 1148
      pos 1164
      pos 1413
      pos 1435
      pos 1460
      pos 1582
      pos 1668
      pos 2504
    doc 18
      freq 2
      pos 1990
      pos 2292
    skipList 
      level 0
        skipDoc 7
        skipDocFP 2645119
        impacts 
          impact 
            freq 3
            norm 100
          impact 
            freq 5
            norm 101
          impact 
            freq 12
            norm 107
          impact 
            freq 31
            norm 113
        impactsEnd 
        skipDoc 15
        skipDocFP 2646712
        impacts 
          impact 
            freq 4
            norm 95
          impact 
            freq 13
            norm 104
          impact 
            freq 15
            norm 109
          impact 
            freq 23
            norm 114
          impact 
            freq 32
            norm 116
        impactsEnd 
  term willats
    doc 2
      freq 1
      pos 3092
  term willens
    doc 2
      freq 1
      pos 3019
  term willing
    doc 3
      freq 1
      pos 5420
    doc 10
      freq 3
      pos 7822
      pos 10546
      pos 10689
    doc 18
      freq 1
      pos 445
  term wimya
    doc 11
      freq 1
      pos 9951
  term window
    doc 7
      freq 1
      pos 1935
    doc 12
      freq 1
      pos 3000
  term wip
    doc 12
      freq 24
      pos 1320
      pos 1443
      pos 1918
      pos 3614
      pos 3633
      pos 4063
      pos 4075
      pos 4680
      pos 4682
      pos 4685
      pos 5256
      pos 6551
      pos 7657
      pos 7676
      pos 7712
      pos 7726
      pos 7742
      pos 7758
      pos 7771
      pos 7788
      pos 7810
      pos 7824
      pos 7842
      pos 7859
  term wire
    doc 0
      freq 3
      pos 7333
      pos 7361
      pos 9030
    doc 1
      freq 2
      pos 4467
      pos 9154
    doc 3
      freq 5
      pos 4521
      pos 4541
      pos 4579
      pos 4599
      pos 4670
    doc 8
      freq 2
      pos 88
      pos 1819
  term wireless
    doc 2
      freq 5
      pos 2640
      pos 2674
      pos 2724
      pos 3298
      pos 3319
    doc 13
      freq 4
      pos 177
      pos 2016
      pos 2642
      pos 4167
    doc 15
      freq 2
      pos 1129
      pos 1189
  term wise
    doc 6
      freq 1
      pos 1211
  term wish
    doc 1
      freq 1
      pos 8874
    doc 10
      freq 2
      pos 4266
      pos 4699
    doc 15
      freq 3
      pos 90
      pos 404
      pos 1590
    doc 16
      freq 1
      pos 1391
    doc 18
      freq 2
      pos 1191
      pos 1883
  term wishes
    doc 3
      freq 1
      pos 5373
  term wishing
    doc 11
      freq 1
      pos 6085
  term with
    doc 0
      freq 63
      pos 102
      pos 703
      pos 727
      pos 830
      pos 882
      pos 932
      pos 1284
      pos 1288
      pos 1298
      pos 1308
      pos 1332
      pos 1344
      pos 1355
      pos 1550
      pos 2199
      pos 2213
      pos 2480
      pos 2924
      pos 3112
      pos 3376
      pos 3837
      pos 4337
      pos 4444
      pos 4842
      pos 4949
      pos 5330
      pos 5690
      pos 5756
      pos 6625
      pos 7334
      pos 7362
      pos 7384
      pos 7417
      pos 7613
      pos 7631
      pos 7711
      pos 7727
      pos 8043
      pos 8064
      pos 8105
      pos 8159
      pos 8196
      pos 9513
      pos 10363
      pos 10429
      pos 10627
      pos 10660
      pos 10689
      pos 10746
      pos 11201
      pos 13089
      pos 13203
      pos 13292
      pos 13353
      pos 13367
      pos 13394
      pos 13423
      pos 13509
      pos 14268
      pos 14339
      pos 14811
      pos 16901
      pos 17406
    doc 1
      freq 44
      pos 964
      pos 1441
      pos 1928
      pos 2286
      pos 2405
      pos 2739
      pos 2923
      pos 3162
      pos 3381
      pos 3516
      pos 3529
      pos 3995
      pos 4309
      pos 4505
      pos 4544
      pos 4794
      pos 4955
      pos 5393
      pos 5419
      pos 5433
      pos 5459
      pos 6006
      pos 6341
      pos 6413
      pos 6542
      pos 6583
      pos 6790
      pos 6832
      pos 6872
      pos 6894
      pos 6928
      pos 7114
      pos 7129
      pos 7460
      pos 7491
      pos 7506
      pos 7560
      pos 7570
      pos 7684
      pos 7992
      pos 8409
      pos 8847
      pos 8864
      pos 9787
    doc 2
      freq 29
      pos 368
      pos 581
      pos 679
      pos 701
      pos 822
      pos 896
      pos 915
      pos 1173
      pos 1696
      pos 1719
      pos 1724
      pos 1880
      pos 2603
      pos 3003
      pos 3397
      pos 3422
      pos 3518
      pos 3592
      pos 3965
      pos 4199
      pos 4279
      pos 4438
      pos 4458
      pos 4492
      pos 4513
      pos 5231
      pos 5740
      pos 6045
      pos 6584
    doc 3
      freq 23
      pos 372
      pos 440
      pos 511
      pos 707
      pos 847
      pos 1532
      pos 1815
      pos 1975
      pos 1990
      pos 2585
      pos 3242
      pos 3402
      pos 3984
      pos 4052
      pos 4184
      pos 4202
      pos 4213
      pos 4434
      pos 4478
      pos 5220
      pos 5257
      pos 5515
      pos 6136
    doc 4
      freq 28
      pos 301
      pos 860
      pos 925
      pos 1275
      pos 1283
      pos 1561
      pos 1599
      pos 1949
      pos 1972
      pos 2175
      pos 2502
      pos 2567
      pos 2609
      pos 2939
      pos 2946
      pos 3120
      pos 3149
      pos 3177
      pos 3386
      pos 3475
      pos 4430
      pos 4438
      pos 4535
      pos 4590
      pos 4647
      pos 4849
      pos 5921
      pos 6291
    doc 5
      freq 6
      pos 106
      pos 541
      pos 2331
      pos 2786
      pos 3422
      pos 4621
    doc 6
      freq 11
      pos 139
      pos 502
      pos 714
      pos 780
      pos 1122
      pos 1363
      pos 1561
      pos 2569
      pos 2587
      pos 2643
      pos 3421
    doc 7
      freq 10
      pos 361
      pos 468
      pos 476
      pos 1128
      pos 1392
      pos 1577
      pos 1616
      pos 2456
      pos 2787
      pos 3126
    doc 8
      freq 2
      pos 778
      pos 2343
    doc 9
      freq 9
      pos 486
      pos 564
      pos 583
      pos 809
      pos 1074
      pos 1094
      pos 1105
      pos 1532
      pos 1988
    doc 10
      freq 65
      pos 237
      pos 248
      pos 599
      pos 620
      pos 956
      pos 1047
      pos 1481
      pos 1516
      pos 1526
      pos 1752
      pos 1816
      pos 1928
      pos 2589
      pos 2638
      pos 2701
      pos 2906
      pos 2936
      pos 3289
      pos 3416
      pos 3951
      pos 4428
      pos 5056
      pos 5210
      pos 5417
      pos 5516
      pos 5908
      pos 5970
      pos 6003
      pos 6040
      pos 6184
      pos 6553
      pos 6595
      pos 6811
      pos 7201
      pos 7258
      pos 7311
      pos 7616
      pos 7778
      pos 7925
      pos 8500
      pos 9121
      pos 9292
      pos 9701
      pos 9722
      pos 9863
      pos 10339
      pos 10356
      pos 10396
      pos 10499
      pos 10551
      pos 10557
      pos 10650
      pos 10656
      pos 10696
      pos 10736
      pos 10768
      pos 10822
      pos 11264
      pos 11435
      pos 11595
      pos 11873
      pos 11947
      pos 12029
      pos 12286
      pos 13649
    doc 11
      freq 76
      pos 175
      pos 270
      pos 278
      pos 375
      pos 409
      pos 416
      pos 465
      pos 480
      pos 502
      pos 509
      pos 526
      pos 1100
      pos 1116
      pos 1169
      pos 1288
      pos 1329
      pos 1336
      pos 1346
      pos 1378
      pos 1704
      pos 1838
      pos 2309
      pos 2533
      pos 2608
      pos 2721
      pos 3569
      pos 4262
      pos 4354
      pos 4382
      pos 4544
      pos 4742
      pos 4798
      pos 4950
      pos 5003
      pos 5087
      pos 5269
      pos 5272
      pos 5282
      pos 5423
      pos 5869
      pos 6137
      pos 6307
      pos 6416
      pos 6528
      pos 6663
      pos 6755
      pos 6798
      pos 6828
      pos 7064
      pos 7198
      pos 7279
      pos 7312
      pos 7412
      pos 7423
      pos 7487
      pos 7610
      pos 7697
      pos 7836
      pos 7904
      pos 7990
      pos 7997
      pos 8087
      pos 8113
      pos 8274
      pos 8373
      pos 8384
      pos 8558
      pos 8650
      pos 8765
      pos 8869
      pos 9011
      pos 9016
      pos 9042
      pos 9147
      pos 9665
      pos 10810
    doc 12
      freq 96
      pos 25
      pos 72
      pos 142
      pos 240
      pos 298
      pos 305
      pos 391
      pos 398
      pos 403
      pos 416
      pos 502
      pos 516
      pos 541
      pos 543
      pos 564
      pos 664
      pos 676
      pos 702
      pos 837
      pos 866
      pos 1001
      pos 1224
      pos 1288
      pos 1561
      pos 1577
      pos 1758
      pos 1946
      pos 2280
      pos 2651
      pos 2896
      pos 3023
      pos 3068
      pos 3143
      pos 3202
      pos 3311
      pos 3339
      pos 3387
      pos 3786
      pos 3816
      pos 3834
      pos 3845
      pos 4198
      pos 4285
      pos 4357
      pos 4429
      pos 4563
      pos 4570
      pos 4631
      pos 4693
      pos 4977
      pos 5014
      pos 5423
      pos 5430
      pos 5437
      pos 5574
      pos 5589
      pos 5618
      pos 5637
      pos 5706
      pos 5859
      pos 5951
      pos 5953
      pos 5982
      pos 6008
      pos 6153
      pos 6159
      pos 6249
      pos 6521
      pos 6550
      pos 6642
      pos 6862
      pos 6971
      pos 6987
      pos 7234
      pos 7463
      pos 7707
      pos 7798
      pos 7887
      pos 7935
      pos 8009
      pos 8137
      pos 8152
      pos 8158
      pos 8240
      pos 8379
      pos 8407
      pos 8579
      pos 8637
      pos 8773
      pos 8853
      pos 8868
      pos 9049
      pos 9128
      pos 9421
      pos 9472
      pos 9660
    doc 13
      freq 28
      pos 529
      pos 654
      pos 961
      pos 1004
      pos 1664
      pos 1683
      pos 1887
      pos 2099
      pos 2317
      pos 2615
      pos 3104
      pos 3358
      pos 3689
      pos 3720
      pos 4076
      pos 4153
      pos 4452
      pos 4649
      pos 4878
      pos 5412
      pos 5955
      pos 6323
      pos 6395
      pos 6457
      pos 6569
      pos 6707
      pos 6724
      pos 7275
    doc 14
      freq 23
      pos 207
      pos 488
      pos 518
      pos 713
      pos 857
      pos 877
      pos 928
      pos 1126
      pos 1324
      pos 1532
      pos 2138
      pos 2250
      pos 2257
      pos 2340
      pos 2497
      pos 2506
      pos 2590
      pos 2640
      pos 2671
      pos 2757
      pos 3867
      pos 5045
      pos 5741
    doc 15
      freq 22
      pos 133
      pos 272
      pos 325
      pos 344
      pos 450
      pos 713
      pos 1469
      pos 1598
      pos 1786
      pos 2353
      pos 2388
      pos 2448
      pos 2602
      pos 2652
      pos 2795
      pos 2804
      pos 2940
      pos 3271
      pos 3727
      pos 3738
      pos 3785
      pos 4260
    doc 16
      freq 8
      pos 120
      pos 288
      pos 1700
      pos 1729
      pos 1963
      pos 2331
      pos 2492
      pos 2871
    doc 17
      freq 17
      pos 181
      pos 325
      pos 577
      pos 591
      pos 690
      pos 694
      pos 1209
      pos 1359
      pos 1525
      pos 1531
      pos 1544
      pos 1632
      pos 1716
      pos 1760
      pos 1782
      pos 1894
      pos 2595
    doc 18
      freq 9
      pos 185
      pos 709
      pos 1039
      pos 1285
      pos 1314
      pos 1350
      pos 1780
      pos 1960
      pos 2383
    skipList 
      level 0
        skipDoc 7
        skipDocFP 2651330
        impacts 
          impact 
            freq 10
            norm 100
          impact 
            freq 11
            norm 101
          impact 
            freq 23
            norm 107
          impact 
            freq 29
            norm 108
          impact 
            freq 44
            norm 113
          impact 
            freq 63
            norm 120
        impactsEnd 
        skipDoc 15
        skipDocFP 2654720
        impacts 
          impact 
            freq 9
            norm 95
          impact 
            freq 22
            norm 104
          impact 
            freq 23
            norm 107
          impact 
            freq 28
            norm 109
          impact 
            freq 96
            norm 113
        impactsEnd 
  term withdraw
    doc 1
      freq 20
      pos 2379
      pos 4255
      pos 4288
      pos 4871
      pos 4926
      pos 4960
      pos 4969
      pos 5054
      pos 5809
      pos 5914
      pos 6892
      pos 6926
      pos 6940
      pos 6971
      pos 6986
      pos 7124
      pos 7146
      pos 7261
      pos 7326
      pos 7877
  term withdrawal
    doc 1
      freq 2
      pos 347
      pos 7093
    doc 2
      freq 1
      pos 6304
  term withdrawals
    doc 1
      freq 2
      pos 2713
      pos 4179
  term withdrawn
    doc 1
      freq 3
      pos 4845
      pos 7274
      pos 7399
  term within
    doc 0
      freq 5
      pos 1313
      pos 1448
      pos 3941
      pos 3972
      pos 12083
    doc 1
      freq 1
      pos 5948
    doc 2
      freq 16
      pos 1212
      pos 1294
      pos 1668
      pos 1789
      pos 1819
      pos 3623
      pos 3662
      pos 4468
      pos 4590
      pos 4633
      pos 5129
      pos 5159
      pos 5227
      pos 5261
      pos 5391
      pos 5843
    doc 3
      freq 6
      pos 140
      pos 489
      pos 869
      pos 920
      pos 4168
      pos 5399
    doc 4
      freq 2
      pos 2526
      pos 3336
    doc 5
      freq 9
      pos 154
      pos 271
      pos 292
      pos 880
      pos 1484
      pos 2212
      pos 2231
      pos 2563
      pos 2911
    doc 6
      freq 2
      pos 2446
      pos 2512
    doc 7
      freq 2
      pos 89
      pos 1328
    doc 8
      freq 1
      pos 452
    doc 9
      freq 3
      pos 405
      pos 572
      pos 620
    doc 10
      freq 13
      pos 202
      pos 460
      pos 3274
      pos 3390
      pos 3494
      pos 3692
      pos 4291
      pos 8330
      pos 8518
      pos 8604
      pos 8695
      pos 13048
      pos 13305
    doc 11
      freq 6
      pos 347
      pos 1219
      pos 4438
      pos 5259
      pos 5412
      pos 6384
    doc 12
      freq 3
      pos 2405
      pos 5743
      pos 7950
    doc 13
      freq 4
      pos 1484
      pos 2899
      pos 2911
      pos 5570
    doc 15
      freq 3
      pos 522
      pos 1771
      pos 1819
    skipList 
      level 0
        skipDoc 7
        skipDocFP 2661723
        impacts 
          impact 
            freq 2
            norm 100
          impact 
            freq 9
            norm 104
          impact 
            freq 16
            norm 108
        impactsEnd 
  term without
    doc 0
      freq 4
      pos 4079
      pos 6665
      pos 14771
      pos 16149
    doc 1
      freq 1
      pos 4586
    doc 2
      freq 4
      pos 929
      pos 2149
      pos 4498
      pos 5608
    doc 3
      freq 3
      pos 2887
      pos 3396
      pos 3563
    doc 4
      freq 6
      pos 1456
      pos 2139
      pos 2434
      pos 2805
      pos 3050
      pos 3286
    doc 5
      freq 3
      pos 2580
      pos 2987
      pos 3749
    doc 6
      freq 4
      pos 410
      pos 488
      pos 504
      pos 2852
    doc 7
      freq 1
      pos 1773
    doc 10
      freq 10
      pos 2664
      pos 8021
      pos 8663
      pos 8683
      pos 8842
      pos 9223
      pos 10119
      pos 11129
      pos 11261
      pos 12908
    doc 11
      freq 4
      pos 793
      pos 4237
      pos 4248
      pos 4591
    doc 12
      freq 5
      pos 2372
      pos 3567
      pos 4121
      pos 7400
      pos 8562
    doc 13
      freq 4
      pos 4313
      pos 4641
      pos 5216
      pos 5917
    doc 14
      freq 2
      pos 108
      pos 2818
    doc 16
      freq 4
      pos 147
      pos 214
      pos 398
      pos 1759
    skipList 
      level 0
        skipDoc 7
        skipDocFP 2663499
        impacts 
          impact 
            freq 1
            norm 100
          impact 
            freq 4
            norm 101
          impact 
            freq 6
            norm 108
        impactsEnd 
  term wjbh
    doc 11
      freq 1
      pos 10410
  term wjk9mkj4m3
    doc 11
      freq 1
      pos 10204
  term wjt1hh
    doc 10
      freq 1
      pos 12494
  term wlan
    doc 2
      freq 1
      pos 5949
  term wly25iw3xynewpecmmo3gnzxpdomstg
    doc 11
      freq 1
      pos 9888
  term wnhf0jpkn3dtnfjv1uirqjxx1t3tf6ok9bivsxhlolc
    doc 11
      freq 1
      pos 10302
  term wnz
    doc 11
      freq 1
      pos 10045
  term wo
    doc 11
      freq 1
      pos 1924
  term won't
    doc 11
      freq 1
      pos 6338
    doc 15
      freq 1
      pos 2749
  term woods
    doc 1
      freq 1
      pos 9579
  term woolf
    doc 18
      freq 1
      pos 2024
  term word
    doc 1
      freq 38
      pos 319
      pos 328
      pos 339
      pos 2004
      pos 2533
      pos 2548
      pos 2554
      pos 2563
      pos 6287
      pos 6295
      pos 6378
      pos 6393
      pos 6401
      pos 6424
      pos 6465
      pos 6473
      pos 6492
      pos 6547
      pos 6574
      pos 6588
      pos 6614
      pos 6621
      pos 6679
      pos 6686
      pos 6715
      pos 6728
      pos 6743
      pos 6748
      pos 6814
      pos 6919
      pos 7005
      pos 7023
      pos 7030
      pos 7048
      pos 7379
      pos 9426
      pos 9431
      pos 9436
    doc 3
      freq 18
      pos 260
      pos 2151
      pos 2159
      pos 2174
      pos 2294
      pos 2974
      pos 3263
      pos 3266
      pos 3279
      pos 3399
      pos 3478
      pos 3518
      pos 3539
      pos 3566
      pos 3586
      pos 3626
      pos 4205
      pos 4325
    doc 4
      freq 1
      pos 5919
    doc 8
      freq 1
      pos 2116
    doc 11
      freq 2
      pos 1767
      pos 1984
  term words
    doc 0
      freq 2
      pos 953
      pos 16945
    doc 1
      freq 2
      pos 1160
      pos 8898
    doc 3
      freq 2
      pos 1235
      pos 4496
    doc 4
      freq 2
      pos 444
      pos 5271
    doc 5
      freq 2
      pos 1048
      pos 4126
    doc 8
      freq 2
      pos 308
      pos 1766
    doc 9
      freq 1
      pos 1669
    doc 10
      freq 3
      pos 676
      pos 1137
      pos 13120
    doc 12
      freq 1
      pos 8948
    doc 13
      freq 2
      pos 1184
      pos 6739
    doc 17
      freq 2
      pos 268
      pos 2031
    doc 18
      freq 1
      pos 2130
    skipList 
      level 0
        skipDoc 10
        skipDocFP 2666649
        impacts 
          impact 
            freq 1
            norm 95
          impact 
            freq 2
            norm 97
          impact 
            freq 3
            norm 116
        impactsEnd 
  term work
    doc 1
      freq 5
      pos 8993
      pos 9010
      pos 9045
      pos 9068
      pos 9094
    doc 2
      freq 48
      pos 131
      pos 762
      pos 793
      pos 858
      pos 954
      pos 979
      pos 1010
      pos 1043
      pos 1050
      pos 1097
      pos 1116
      pos 1149
      pos 1210
      pos 1700
      pos 1970
      pos 1986
      pos 2332
      pos 2345
      pos 2474
      pos 2813
      pos 2832
      pos 2841
      pos 3583
      pos 3899
      pos 3924
      pos 3980
      pos 4059
      pos 4229
      pos 4242
      pos 4248
      pos 4267
      pos 4381
      pos 4630
      pos 4752
      pos 4767
      pos 4848
      pos 4948
      pos 4973
      pos 5052
      pos 5172
      pos 5212
      pos 5617
      pos 5691
      pos 5711
      pos 5761
      pos 5808
      pos 5932
      pos 5991
    doc 3
      freq 6
      pos 1739
      pos 4546
      pos 4604
      pos 4637
      pos 4656
      pos 4676
    doc 4
      freq 3
      pos 912
      pos 1691
      pos 5446
    doc 5
      freq 2
      pos 4250
      pos 4391
    doc 6
      freq 1
      pos 104
    doc 7
      freq 2
      pos 643
      pos 1409
    doc 8
      freq 11
      pos 1825
      pos 1840
      pos 1859
      pos 1883
      pos 1900
      pos 1920
      pos 1957
      pos 1981
      pos 2033
      pos 2049
      pos 2094
    doc 10
      freq 8
      pos 1602
      pos 2235
      pos 7765
      pos 10682
      pos 11116
      pos 11319
      pos 11429
      pos 13374
    doc 11
      freq 2
      pos 9516
      pos 9709
    doc 12
      freq 15
      pos 2463
      pos 4037
      pos 4514
      pos 7671
      pos 7693
      pos 7721
      pos 7737
      pos 7753
      pos 7766
      pos 7783
      pos 7805
      pos 7819
      pos 7837
      pos 7854
      pos 7873
    doc 13
      freq 4
      pos 1152
      pos 1160
      pos 6823
      pos 6986
    doc 14
      freq 1
      pos 5500
    doc 15
      freq 4
      pos 182
      pos 2462
      pos 3692
      pos 3724
    skipList 
      level 0
        skipDoc 8
        skipDocFP 2667551
        impacts 
          impact 
            freq 11
            norm 97
          impact 
            freq 48
            norm 108
        impactsEnd 
  term worked
    doc 2
      freq 3
      pos 3633
      pos 4278
      pos 4784
  term working
    doc 0
      freq 4
      pos 1
      pos 1086
      pos 1095
      pos 12023
    doc 1
      freq 1
      pos 1
    doc 2
      freq 12
      pos 1
      pos 400
      pos 429
      pos 440
      pos 488
      pos 783
      pos 1409
      pos 1715
      pos 2373
      pos 4074
      pos 4221
      pos 4327
    doc 3
      freq 1
      pos 1
    doc 4
      freq 5
      pos 1
      pos 4847
      pos 4850
      pos 5464
      pos 5468
    doc 5
      freq 3
      pos 1
      pos 3796
      pos 4012
    doc 6
      freq 1
      pos 1
    doc 7
      freq 6
      pos 1
      pos 399
      pos 436
      pos 624
      pos 1467
      pos 1581
    doc 8
      freq 3
      pos 1
      pos 93
      pos 213
    doc 9
      freq 1
      pos 1
    doc 10
      freq 1
      pos 1
    doc 11
      freq 1
      pos 1
    doc 12
      freq 2
      pos 1
      pos 8873
    doc 13
      freq 4
      pos 1
      pos 378
      pos 1174
      pos 1564
    doc 14
      freq 1
      pos 1
    doc 15
      freq 1
      pos 1
    doc 16
      freq 2
      pos 1
      pos 1584
    doc 17
      freq 2
      pos 1
      pos 1979
    doc 18
      freq 4
      pos 1
      pos 517
      pos 521
      pos 1218
    skipList 
      level 0
        skipDoc 7
        skipDocFP 2669880
        impacts 
          impact 
            freq 6
            norm 100
          impact 
            freq 12
            norm 108
        impactsEnd 
        skipDoc 15
        skipDocFP 2670529
        impacts 
          impact 
            freq 1
            norm 95
          impact 
            freq 3
            norm 97
          impact 
            freq 4
            norm 109
        impactsEnd 
  term works
    doc 10
      freq 1
      pos 1396
    doc 12
      freq 1
      pos 4426
    doc 18
      freq 1
      pos 871
  term world
    doc 7
      freq 1
      pos 91
    doc 10
      freq 1
      pos 9655
  term worse
    doc 12
      freq 1
      pos 1013
  term worst
    doc 6
      freq 2
      pos 1536
      pos 1568
    doc 10
      freq 1
      pos 9484
  term worth
    doc 6
      freq 1
      pos 1295
    doc 7
      freq 1
      pos 1284
    doc 10
      freq 2
      pos 11010
      pos 11367
    doc 12
      freq 3
      pos 1161
      pos 6857
      pos 9155
    doc 15
      freq 2
      pos 706
      pos 3089
    doc 18
      freq 1
      pos 1752
  term would
    doc 0
      freq 3
      pos 3205
      pos 6691
      pos 15899
    doc 1
      freq 4
      pos 2124
      pos 3251
      pos 7522
      pos 8818
    doc 2
      freq 4
      pos 3455
      pos 4387
      pos 5077
      pos 5580
    doc 4
      freq 6
      pos 920
      pos 949
      pos 1201
      pos 1235
      pos 3490
      pos 4383
    doc 5
      freq 3
      pos 2288
      pos 4067
      pos 4086
    doc 6
      freq 2
      pos 1343
      pos 2110
    doc 7
      freq 5
      pos 571
      pos 1158
      pos 1507
      pos 1568
      pos 1768
    doc 9
      freq 3
      pos 1349
      pos 1382
      pos 1504
    doc 10
      freq 24
      pos 744
      pos 772
      pos 1209
      pos 1289
      pos 3569
      pos 3608
      pos 4368
      pos 5674
      pos 5720
      pos 5877
      pos 7099
      pos 8246
      pos 8771
      pos 8873
      pos 8926
      pos 9341
      pos 9482
      pos 9736
      pos 9790
      pos 9831
      pos 9926
      pos 10001
      pos 12105
      pos 12275
    doc 11
      freq 20
      pos 1292
      pos 1383
      pos 1392
      pos 1420
      pos 1427
      pos 2512
      pos 2529
      pos 3274
      pos 3305
      pos 3592
      pos 4120
      pos 5445
      pos 7597
      pos 7606
      pos 7818
      pos 7824
      pos 7833
      pos 7929
      pos 8111
      pos 8428
    doc 12
      freq 42
      pos 1362
      pos 1375
      pos 1425
      pos 1464
      pos 2093
      pos 2367
      pos 2384
      pos 2630
      pos 2702
      pos 2991
      pos 2997
      pos 3049
      pos 3205
      pos 3401
      pos 3576
      pos 3896
      pos 3922
      pos 3934
      pos 4598
      pos 4604
      pos 5036
      pos 5144
      pos 5197
      pos 5293
      pos 5367
      pos 5753
      pos 5989
      pos 5994
      pos 6102
      pos 6130
      pos 6432
      pos 8570
      pos 8606
      pos 8827
      pos 8907
      pos 8934
      pos 8955
      pos 8969
      pos 9144
      pos 9254
      pos 9262
      pos 9380
    doc 13
      freq 7
      pos 1986
      pos 4694
      pos 5229
      pos 5320
      pos 5335
      pos 5360
      pos 6956
    doc 14
      freq 7
      pos 342
      pos 375
      pos 525
      pos 1145
      pos 2653
      pos 2787
      pos 5339
    doc 15
      freq 3
      pos 2659
      pos 3448
      pos 3880
    doc 16
      freq 2
      pos 1037
      pos 1051
    doc 17
      freq 1
      pos 1506
    doc 18
      freq 2
      pos 1059
      pos 2038
    skipList 
      level 0
        skipDoc 9
        skipDocFP 2672255
        impacts 
          impact 
            freq 3
            norm 95
          impact 
            freq 5
            norm 100
          impact 
            freq 6
            norm 108
        impactsEnd 
        skipDoc 17
        skipDocFP 2672887
        impacts 
          impact 
            freq 1
            norm 98
          impact 
            freq 2
            norm 99
          impact 
            freq 3
            norm 104
          impact 
            freq 7
            norm 107
          impact 
            freq 42
            norm 113
        impactsEnd 
  term wp8pg
    doc 10
      freq 1
      pos 12789
  term wpi
    doc 10
      freq 1
      pos 12597
  term wrapped
    doc 0
      freq 1
      pos 681
    doc 14
      freq 2
      pos 1105
      pos 1751
  term wraps
    doc 0
      freq 1
      pos 13017
    doc 10
      freq 2
      pos 6474
      pos 7224
    doc 14
      freq 4
      pos 3862
      pos 4608
      pos 5040
      pos 5176
  term wrinkles
    doc 10
      freq 1
      pos 3478
  term writabl
    doc 0
      freq 1
      pos 16646
  term write
    doc 0
      freq 76
      pos 2258
      pos 2337
      pos 2390
      pos 2438
      pos 2472
      pos 2549
      pos 2618
      pos 2670
      pos 2728
      pos 2775
      pos 2813
      pos 2861
      pos 2980
      pos 4760
      pos 4829
      pos 4968
      pos 5033
      pos 5145
      pos 5174
      pos 5204
      pos 6406
      pos 6447
      pos 6473
      pos 6786
      pos 6845
      pos 6939
      pos 6986
      pos 7026
      pos 7104
      pos 7161
      pos 14829
      pos 14841
      pos 14853
      pos 14865
      pos 14877
      pos 14889
      pos 14901
      pos 14913
      pos 14937
      pos 14949
      pos 14961
      pos 14973
      pos 14985
      pos 14997
      pos 15009
      pos 15021
      pos 15033
      pos 15057
      pos 15069
      pos 15081
      pos 15093
      pos 15105
      pos 15117
      pos 15129
      pos 15141
      pos 15153
      pos 15165
      pos 15189
      pos 15201
      pos 15213
      pos 15225
      pos 15237
      pos 15249
      pos 15261
      pos 15273
      pos 15285
      pos 15297
      pos 15321
      pos 15333
      pos 15345
      pos 15357
      pos 15369
      pos 15381
      pos 15393
      pos 16110
      pos 16710
    doc 7
      freq 2
      pos 413
      pos 573
    doc 15
      freq 1
      pos 3443
  term writers
    doc 17
      freq 1
      pos 993
  term writing
    doc 2
      freq 2
      pos 189
      pos 6347
    doc 5
      freq 1
      pos 4149
    doc 8
      freq 1
      pos 1733
    doc 12
      freq 1
      pos 4044
    doc 16
      freq 1
      pos 1155
  term written
    doc 2
      freq 3
      pos 2050
      pos 3610
      pos 4145
  term wroclawsk
    doc 6
      freq 1
      pos 2952
  term wrong
    doc 0
      freq 1
      pos 13425
    doc 1
      freq 5
      pos 2354
      pos 6896
      pos 6930
      pos 7840
      pos 9482
    doc 12
      freq 1
      pos 1705
  term wsinv
    doc 11
      freq 1
      pos 1448
  term wsinv.ndaksdj
    doc 11
      freq 1
      pos 1474
  term wsqmctx56eqgqx
    doc 11
      freq 1
      pos 10376
  term wwfwydvr0jbhgwdoau0z
    doc 10
      freq 1
      pos 6900
  term www
    doc 13
      freq 1
      pos 6798
  term www.cs.columbia.edu
    doc 11
      freq 1
      pos 10612
  term www.drizzle.com
    doc 2
      freq 1
      pos 2282
  term www.dvb.org
    doc 13
      freq 1
      pos 6809
  term www.example.com
    doc 11
      freq 1
      pos 7645
    doc 12
      freq 1
      pos 4670
  term www.iana.org
    doc 4
      freq 1
      pos 5063
    doc 10
      freq 5
      pos 11519
      pos 11622
      pos 11717
      pos 11818
      pos 11912
    doc 16
      freq 1
      pos 1662
  term www.ieee802
    doc 2
      freq 1
      pos 2891
  term www.ietf.org
    doc 0
      freq 2
      pos 1098
      pos 17480
    doc 1
      freq 1
      pos 9861
    doc 2
      freq 5
      pos 2362
      pos 2383
      pos 2444
      pos 2824
      pos 6658
    doc 3
      freq 1
      pos 6210
    doc 4
      freq 1
      pos 6365
    doc 5
      freq 1
      pos 4695
    doc 6
      freq 1
      pos 3495
    doc 7
      freq 1
      pos 3200
    doc 8
      freq 1
      pos 2417
    doc 9
      freq 1
      pos 2062
    doc 10
      freq 1
      pos 13723
    doc 11
      freq 1
      pos 10884
    doc 12
      freq 1
      pos 9734
    doc 13
      freq 1
      pos 7349
    doc 14
      freq 1
      pos 5815
    doc 15
      freq 1
      pos 4334
    doc 16
      freq 1
      pos 2945
    doc 17
      freq 1
      pos 2669
    doc 18
      freq 1
      pos 2457
    skipList 
      level 0
        skipDoc 7
        skipDocFP 2678656
        impacts 
          impact 
            freq 1
            norm 100
          impact 
            freq 5
            norm 108
        impactsEnd 
        skipDoc 15
        skipDocFP 2679036
        impacts 
          impact 
            freq 1
            norm 95
        impactsEnd 
  term www.jdrosen.net
    doc 11
      freq 1
      pos 10584
  term www.neustar.biz
    doc 10
      freq 1
      pos 13428
  term www.qualcomm.com
    doc 16
      freq 1
      pos 2674
  term www.rfc
    doc 6
      freq 1
      pos 3258
  term wycomb
    doc 1
      freq 1
      pos 9549
    doc 3
      freq 1
      pos 5914
  term wzt
    doc 11
      freq 1
      pos 10009
  term x
    doc 0
      freq 12
      pos 3829
      pos 3836
      pos 3854
      pos 4329
      pos 4336
      pos 4354
      pos 5389
      pos 5401
      pos 10369
      pos 11193
      pos 11200
      pos 11218
    doc 3
      freq 1
      pos 4570
    doc 5
      freq 9
      pos 1221
      pos 1237
      pos 1345
      pos 1916
      pos 1919
      pos 2080
      pos 2083
      pos 2099
      pos 2101
    doc 7
      freq 23
      pos 716
      pos 739
      pos 861
      pos 916
      pos 930
      pos 934
      pos 959
      pos 1017
      pos 1197
      pos 1928
      pos 1953
      pos 2024
      pos 2040
      pos 2083
      pos 2135
      pos 2145
      pos 2271
      pos 2380
      pos 2394
      pos 2398
      pos 2403
      pos 2528
      pos 2557
    doc 8
      freq 4
      pos 947
      pos 949
      pos 964
      pos 970
    doc 10
      freq 2
      pos 13237
      pos 13260
    doc 11
      freq 3
      pos 10185
      pos 10331
      pos 10355
    doc 16
      freq 3
      pos 1738
      pos 1996
      pos 2364
    doc 17
      freq 10
      pos 449
      pos 453
      pos 592
      pos 1997
      pos 2004
      pos 2057
      pos 2091
      pos 2093
      pos 2122
      pos 2127
    skipList 
      level 0
        skipDoc 16
        skipDocFP 2680221
        impacts 
          impact 
            freq 4
            norm 97
          impact 
            freq 23
            norm 100
        impactsEnd 
  term x01
    doc 16
      freq 1
      pos 1522
  term x0b
    doc 16
      freq 1
      pos 1524
  term x0e
    doc 16
      freq 1
      pos 1526
  term x20
    doc 10
      freq 1
      pos 4995
  term x5
    doc 11
      freq 1
      pos 10276
  term x5d
    doc 16
      freq 1
      pos 1528
  term x7c
    doc 10
      freq 1
      pos 4906
  term x9u
    doc 11
      freq 1
      pos 10000
  term xadfilhxv
    doc 10
      freq 1
      pos 12745
  term xbb3ulpoohcbwfk9mtrlmb6cs9ql66kgwnll9ukehhhyozgatdxeobcyhusogdsu
    doc 10
      freq 1
      pos 6237
  term xbnsu8fc58bpsr9fopnioja5q9rjft4lpsn
    doc 11
      freq 1
      pos 10252
  term xc3oeo55qrizh3yicvskk9n9olanjtqnjvahyvruze5f
    doc 10
      freq 1
      pos 6888
  term xdw2zc2hm2nexng6un3lrf0qfaikjdyxwdnkmohyopvrit
    doc 11
      freq 1
      pos 9875
  term xeqhoximszduzut2i2qeqftsyt9j4suzz3wwhhfkxa4ev4atdkcjn0tub7ob
    doc 10
      freq 1
      pos 12589
  term xf6iibjrfvp7fbdbv
    doc 11
      freq 1
      pos 9904
  term xf6orxq7fq5flpy3exf1z9
    doc 11
      freq 1
      pos 10466
  term xgfrb2zdbu0vorxrdoz04qmyripxg1lemneogcocyrxrbvq5p6wbzaceqk0
    doc 10
      freq 1
      pos 6281
  term xgnqdskxixptk9dpkfmc5ds
    doc 11
      freq 1
      pos 9910
  term xh49gyj
    doc 11
      freq 1
      pos 9974
  term xiao
    doc 3
      freq 2
      pos 4569
      pos 4886
  term xipeng
    doc 3
      freq 1
      pos 4885
  term xislk20gg9ucen24ga1wm38vwonxe76mcziz8s
    doc 11
      freq 1
      pos 10480
  term xj48ruolxbimahm43skjqyv6sxzaewhmwxx7xswlafsbj2aszxjdle3ls
    doc 11
      freq 1
      pos 10472
  term xjivqoqx9bcwy
    doc 10
      freq 1
      pos 12652
  term xk8jwos44ansava6tviolac8lhpu9z9x4n8ihntourax52r3
    doc 10
      freq 1
      pos 12635
  term xlgketa0olvq0rt70q5jisfbqmjmqf
    doc 11
      freq 1
      pos 3807
  term xmb8dma8oxdp9e2l1ersqco0j
    doc 11
      freq 1
      pos 10046
  term xml
    doc 11
      freq 2
      pos 845
      pos 851
    doc 13
      freq 2
      pos 1959
      pos 1992
  term xn2ahvqy2ahlp
    doc 11
      freq 1
      pos 10361
  term xnlxelfx702lcijvurz8ods
    doc 10
      freq 1
      pos 12805
  term xnn
    doc 11
      freq 1
      pos 9928
  term xns
    doc 7
      freq 2
      pos 1090
      pos 2683
  term xnscp
    doc 7
      freq 2
      pos 1094
      pos 2687
  term xr
    doc 6
      freq 1
      pos 3057
  term xr6pwe9c
    doc 10
      freq 1
      pos 12739
  term xsswv6k
    doc 10
      freq 1
      pos 12675
  term xstyoqgpfdc6
    doc 10
      freq 1
      pos 12580
  term xuzlupprpi9tmdkxw4r
    doc 11
      freq 1
      pos 9944
  term xve9mzydnhfwl3lj1qunjotean4jzchat8m
    doc 11
      freq 1
      pos 10459
  term xxiao
    doc 3
      freq 1
      pos 4898
  term xxydxsnxafj2y226z3opk4c5u
    doc 11
      freq 1
      pos 9914
  term xzofxlbtlgo62
    doc 11
      freq 1
      pos 10152
  term xzu5gwasy5ujv
    doc 10
      freq 1
      pos 6869
  term xzvf
    doc 10
      freq 1
      pos 12378
    doc 11
      freq 1
      pos 9795
  term y
    doc 1
      freq 6
      pos 8937
      pos 9001
      pos 9415
      pos 9429
      pos 9434
      pos 9439
    doc 2
      freq 1
      pos 3335
    doc 3
      freq 4
      pos 885
      pos 887
      pos 902
      pos 904
    doc 8
      freq 3
      pos 1891
      pos 2038
      pos 2062
    doc 10
      freq 2
      pos 11528
      pos 12468
    doc 11
      freq 1
      pos 10271
    doc 12
      freq 3
      pos 7017
      pos 7350
      pos 7370
    doc 13
      freq 2
      pos 3
      pos 6856
    skipList 
      level 0
        skipDoc 13
        skipDocFP 2684725
        impacts 
          impact 
            freq 3
            norm 97
          impact 
            freq 4
            norm 107
          impact 
            freq 6
            norm 113
        impactsEnd 
  term y3h6p6nq
    doc 11
      freq 1
      pos 9939
  term y5uf56x4fcxhkmz
    doc 11
      freq 1
      pos 9945
  term y8yp9187olyycyx9rd
    doc 11
      freq 1
      pos 10072
  term ya1xs6aebq
    doc 11
      freq 1
      pos 10130
  term yang
    doc 2
      freq 1
      pos 3305
  term yateusw5gu7v1g
    doc 10
      freq 1
      pos 6913
  term ybv9b8wg
    doc 10
      freq 1
      pos 12632
  term yco4rk
    doc 10
      freq 1
      pos 12513
  term yd
    doc 11
      freq 1
      pos 10273
  term yd2dih6dznby
    doc 10
      freq 1
      pos 6259
  term yeaifv4
    doc 10
      freq 1
      pos 12558
  term year
    doc 9
      freq 1
      pos 1347
    doc 12
      freq 1
      pos 5776
  term years
    doc 6
      freq 1
      pos 308
    doc 7
      freq 1
      pos 1640
    doc 9
      freq 1
      pos 1355
    doc 13
      freq 1
      pos 371
    doc 15
      freq 2
      pos 2415
      pos 3592
  term yet
    doc 1
      freq 1
      pos 6518
    doc 2
      freq 5
      pos 1690
      pos 3687
      pos 5274
      pos 5994
      pos 6005
    doc 12
      freq 3
      pos 2771
      pos 3782
      pos 6055
  term yf8gz4tztiwh
    doc 11
      freq 1
      pos 10201
  term ygxev
    doc 10
      freq 1
      pos 12569
  term yhnkqagct
    doc 11
      freq 1
      pos 9896
  term yhw6rzmfcx
    doc 10
      freq 1
      pos 6903
  term yid
    doc 10
      freq 1
      pos 6912
  term yigal
    doc 3
      freq 1
      pos 4920
  term yin
    doc 11
      freq 1
      pos 9491
  term ykmlvkrlaaseajl
    doc 11
      freq 1
      pos 10238
  term ykuqvkf1v
    doc 11
      freq 1
      pos 10319
  term yl
    doc 11
      freq 1
      pos 10396
  term ymnf4nickbtv
    doc 11
      freq 1
      pos 9994
  term ynpqze2vjdw
    doc 11
      freq 1
      pos 9905
  term yo4jh
    doc 11
      freq 1
      pos 10144
  term yoiecnyckk1e9fd0dducjsariawzwudqf
    doc 11
      freq 1
      pos 10395
  term york
    doc 11
      freq 1
      pos 10598
    doc 13
      freq 1
      pos 7069
  term you
    doc 10
      freq 9
      pos 1074
      pos 1077
      pos 1089
      pos 1092
      pos 1103
      pos 1123
      pos 1130
      pos 1139
      pos 1153
    doc 12
      freq 1
      pos 8267
    doc 15
      freq 3
      pos 2384
      pos 2441
      pos 2455
  term your
    doc 10
      freq 1
      pos 1163
    doc 16
      freq 1
      pos 2235
  term yp
    doc 10
      freq 1
      pos 12791
  term ypecssvpykuv4tpb5ne9xneo8kxqvxnk3cqn
    doc 10
      freq 1
      pos 12479
  term ypk3ckffzoyfjelcgpxxzq2qzuhzgtdxz9paepwx4rsk
    doc 10
      freq 1
      pos 6241
  term ypuq4hly8kyus6wbz3lib0tnxx2xmpodd9ewqpv1vlb8dgvdbr2s4dnwbnzvirlp
    doc 10
      freq 1
      pos 12545
  term ypztnb8m7
    doc 11
      freq 1
      pos 10226
  term yrlbyyqtlqwzj
    doc 10
      freq 2
      pos 6562
      pos 6655
  term ytop3dcsnqyfzp
    doc 10
      freq 1
      pos 12559
  term yuji
    doc 13
      freq 1
      pos 6989
  term yunkccq66gtediegqw29o0lqngtub9
    doc 10
      freq 1
      pos 12629
  term yvtze2hfux5pkvxvxv
    doc 11
      freq 1
      pos 10227
  term yxuz
    doc 10
      freq 1
      pos 12743
  term yzi5y5
    doc 10
      freq 1
      pos 12585
  term z
    doc 0
      freq 1
      pos 15954
    doc 10
      freq 5
      pos 6863
      pos 12497
      pos 12633
      pos 12768
      pos 12817
    doc 11
      freq 3
      pos 2469
      pos 2560
      pos 2565
    doc 14
      freq 3
      pos 1972
      pos 2001
      pos 2208
  term z12xoi5kxvqplbl34wg
    doc 11
      freq 1
      pos 10017
  term z3
    doc 10
      freq 1
      pos 12672
  term z4p
    doc 10
      freq 1
      pos 12734
  term z6jq1lsgftelvwpy2bvuffjmph06ll0cjsq
    doc 10
      freq 1
      pos 6209
  term z9f
    doc 11
      freq 1
      pos 5464
  term z9hg4bk
    doc 11
      freq 5
      pos 1939
      pos 3784
      pos 4480
      pos 7035
      pos 7122
  term z9hg4bk0a9idfne
    doc 11
      freq 1
      pos 3677
  term z9hg4bk1324923
    doc 11
      freq 2
      pos 4015
      pos 8477
  term z9hg4bk1saber23
    doc 11
      freq 1
      pos 8484
  term z9hg4bk209
    doc 11
      freq 1
      pos 2581
  term z9hg4bk2398ndao
    doc 11
      freq 2
      pos 4139
      pos 6977
  term z9hg4bk293423
    doc 11
      freq 1
      pos 8327
  term z9hg4bk2980unddj
    doc 11
      freq 1
      pos 3661
  term z9hg4bk299342093
    doc 11
      freq 1
      pos 5800
  term z9hg4bk30239
    doc 11
      freq 1
      pos 1521
  term z9hg4bk342sdfoi3
    doc 11
      freq 1
      pos 4912
  term z9hg4bk9ikj8
    doc 11
      freq 1
      pos 1515
  term z9hg4bkasd0f3en
    doc 11
      freq 1
      pos 3669
  term z9hg4bkkdj.insuf
    doc 11
      freq 1
      pos 7221
  term z9hg4bkkdju43234
    doc 11
      freq 1
      pos 6447
  term z9hg4bkkdjuw
    doc 11
      freq 22
      pos 2229
      pos 2390
      pos 2705
      pos 3553
      pos 3645
      pos 4692
      pos 5972
      pos 6183
      pos 6373
      pos 6608
      pos 6684
      pos 6792
      pos 6887
      pos 7667
      pos 7770
      pos 7879
      pos 8065
      pos 8137
      pos 8736
      pos 8826
      pos 8943
      pos 9100
  term z9hg4bkkdjuw2349
    doc 11
      freq 1
      pos 8627
  term z9hg4bkkdjuw23492
    doc 11
      freq 1
      pos 3359
  term z9hg4bkkdjuw2395
    doc 11
      freq 1
      pos 5488
  term z9hg4bkkdjuw380234
    doc 11
      freq 1
      pos 3393
  term z9hg4bkkdjuw3923
    doc 11
      freq 1
      pos 5648
  term z9hg4bkkdjuw39234
    doc 11
      freq 3
      pos 5187
      pos 7405
      pos 7536
  term z9hg4bkklasjdhf
    doc 11
      freq 1
      pos 3653
  term z9hg4bknashds10
    doc 10
      freq 3
      pos 6984
      pos 7121
      pos 7334
  term z9hg4bknashds8
    doc 10
      freq 2
      pos 6333
      pos 6618
  term z9hg4bkzzxdiwo34sw
    doc 11
      freq 1
      pos 5033
  term z9lsrwmt6439i7fvntfnwyz
    doc 11
      freq 1
      pos 10224
  term z9vp5p
    doc 11
      freq 1
      pos 10310
  term zanbgkqhkig9w0baqufaaobgqbiykhit8txfgnfpnjxi5jcizoxmy8y
    doc 10
      freq 1
      pos 6907
  term zbr
    doc 10
      freq 1
      pos 12617
  term zdf
    doc 11
      freq 1
      pos 10277
  term zdfrxf9vimen2bgpuqwr3l6jdzo3uent51
    doc 11
      freq 1
      pos 10465
  term ze
    doc 11
      freq 1
      pos 2479
  term zelig
    doc 1
      freq 1
      pos 8984
    doc 3
      freq 3
      pos 4534
      pos 4591
      pos 4916
    doc 8
      freq 1
      pos 1874
  term zellerfeld
    doc 15
      freq 1
      pos 4055
  term zerfos
    doc 2
      freq 1
      pos 3307
  term zero
    doc 0
      freq 13
      pos 1553
      pos 3379
      pos 4601
      pos 4628
      pos 5054
      pos 5283
      pos 5316
      pos 5562
      pos 6707
      pos 6766
      pos 7584
      pos 8246
      pos 13296
    doc 1
      freq 2
      pos 2099
      pos 2732
    doc 3
      freq 1
      pos 3910
    doc 4
      freq 11
      pos 543
      pos 703
      pos 1342
      pos 2217
      pos 2837
      pos 3104
      pos 3125
      pos 3136
      pos 3618
      pos 3651
      pos 3653
    doc 6
      freq 2
      pos 1285
      pos 2073
    doc 11
      freq 4
      pos 476
      pos 3240
      pos 8551
      pos 8567
    doc 14
      freq 1
      pos 2384
    doc 18
      freq 2
      pos 1289
      pos 1323
    skipList 
      level 0
        skipDoc 18
        skipDocFP 2692172
        impacts 
          impact 
            freq 2
            norm 97
          impact 
            freq 11
            norm 108
          impact 
            freq 13
            norm 120
        impactsEnd 
  term zeromf
    doc 11
      freq 1
      pos 8600
  term zeromf.jfasdlfnm2o2l43r5u0asdfas
    doc 11
      freq 1
      pos 8616
  term zeros
    doc 0
      freq 1
      pos 10690
    doc 10
      freq 1
      pos 5038
    doc 11
      freq 1
      pos 1348
    doc 18
      freq 2
      pos 1351
      pos 1355
  term zfj0zpegl7wdgllgxoc9w
    doc 11
      freq 1
      pos 10307
  term zfxpz9p5fewv8vwx
    doc 10
      freq 1
      pos 12794
  term zh
    doc 7
      freq 1
      pos 2906
  term zhang
    doc 2
      freq 1
      pos 6373
    doc 6
      freq 1
      pos 2872
  term zhao
    doc 0
      freq 1
      pos 15975
  term zhfoffs
    doc 10
      freq 1
      pos 12753
  term zill
    doc 4
      freq 1
      pos 5497
  term zip
    doc 16
      freq 1
      pos 1739
  term zjh6p0a9bej
    doc 11
      freq 1
      pos 10367
  term zjni8v5b4wwaxjkjtnfhlmwvrymzixybfji5jfzinzwlzzr0gmoagoi39e6enyek
    doc 10
      freq 1
      pos 12572
  term zk
    doc 11
      freq 1
      pos 1983
  term zl7yy71yzetcymunfin1rk0mgur3y5osbhz9bhayvlyveewnvwn6bf8
    doc 10
      freq 1
      pos 12630
  term zm8drvexip4js2h7t4rciv
    doc 11
      freq 1
      pos 9955
  term zmclfccmvuh3f3t7x4
    doc 11
      freq 1
      pos 10256
  term zmfva6kmp8s6fyzmkbj7rdcoudzwydscq
    doc 10
      freq 1
      pos 12518
  term zmx1zmz5lw1hyy0xni5sb2nhb
    doc 11
      freq 1
      pos 3825
  term zo3
    doc 11
      freq 1
      pos 10449
  term zone
    doc 0
      freq 3
      pos 3822
      pos 4322
      pos 11186
    doc 7
      freq 2
      pos 2864
      pos 2876
    doc 11
      freq 3
      pos 6031
      pos 6047
      pos 6130
    doc 12
      freq 14
      pos 2829
      pos 3088
      pos 3187
      pos 3191
      pos 4319
      pos 4338
      pos 4348
      pos 4928
      pos 6228
      pos 6293
      pos 6380
      pos 8195
      pos 9295
      pos 9399
    doc 14
      freq 29
      pos 117
      pos 293
      pos 374
      pos 539
      pos 708
      pos 1084
      pos 1111
      pos 1209
      pos 1372
      pos 1758
      pos 2077
      pos 2422
      pos 2467
      pos 2474
      pos 2481
      pos 2583
      pos 2664
      pos 2687
      pos 2849
      pos 2895
      pos 3858
      pos 3875
      pos 4605
      pos 4615
      pos 4983
      pos 5036
      pos 5053
      pos 5156
      pos 5183
    doc 18
      freq 25
      pos 133
      pos 148
      pos 198
      pos 269
      pos 276
      pos 278
      pos 283
      pos 305
      pos 319
      pos 335
      pos 337
      pos 425
      pos 438
      pos 441
      pos 527
      pos 551
      pos 646
      pos 666
      pos 700
      pos 838
      pos 1147
      pos 1189
      pos 1777
      pos 1794
      pos 1880
  term zone's
    doc 18
      freq 3
      pos 1167
      pos 1659
      pos 1730
  term zones
    doc 12
      freq 5
      pos 757
      pos 768
      pos 5665
      pos 7969
      pos 9378
    doc 14
      freq 7
      pos 208
      pos 489
      pos 1127
      pos 1257
      pos 1298
      pos 2507
      pos 2519
    doc 18
      freq 1
      pos 1733
  term zorn
    doc 2
      freq 4
      pos 3047
      pos 3066
      pos 3106
      pos 3165
  term zs5jb20wgz8wdqyjkozihvcnaqebbqadgy0amigjaogbam88wg0dwg
    doc 10
      freq 1
      pos 6253
  term zt6msxyqzx9yge6u8
    doc 11
      freq 1
      pos 10496
  term zt88stf
    doc 10
      freq 1
      pos 12713
  term zu7nzixuqososw89kbdun8yg08bgzvp26snxxisvklnowyav
    doc 11
      freq 1
      pos 10069
  term zwywkulfjuftlevw
    doc 10
      freq 1
      pos 12773
  term zyjssidxcypsxr1l
    doc 11
      freq 1
      pos 10162
  term zynbbhc00vmzr2kzt6vmcvponwjmgvqtbdqghowelxjfzb2a1pxar3vgrb0sssa
    doc 10
      freq 2
      pos 6559
      pos 6652
  term zyplz
    doc 11
      freq 1
      pos 10134
field titolo
  term rfc4441
    doc 2
      freq 1
      pos 0
  term rfc4442
    doc 5
      freq 1
      pos 0
  term rfc4443
    doc 4
      freq 1
      pos 0
  term rfc4444
    doc 0
      freq 1
      pos 0
  term rfc4445
    doc 6
      freq 1
      pos 0
  term rfc4446
    doc 8
      freq 1
      pos 0
  term rfc4447
    doc 1
      freq 1
      pos 0
  term rfc4448
    doc 3
      freq 1
      pos 0
  term rfc4449
    doc 9
      freq 1
      pos 0
  term rfc4450
    doc 7
      freq 1
      pos 0
  term rfc4469
    doc 16
      freq 1
      pos 0
  term rfc4470
    doc 18
      freq 1
      pos 0
  term rfc4471
    doc 14
      freq 1
      pos 0
  term rfc4472
    doc 12
      freq 1
      pos 0
  term rfc4473
    doc 13
      freq 1
      pos 0
  term rfc4474
    doc 10
      freq 1
      pos 0
  term rfc4475
    doc 11
      freq 1
      pos 0
  term rfc4476
    doc 17
      freq 1
      pos 0
  term rfc4477
    doc 15
      freq 1
      pos 0
  term txt
    doc 0
      freq 1
      pos 1
    doc 1
      freq 1
      pos 1
    doc 2
      freq 1
      pos 1
    doc 3
      freq 1
      pos 1
    doc 4
      freq 1
      pos 1
    doc 5
      freq 1
      pos 1
    doc 6
      freq 1
      pos 1
    doc 7
      freq 1
      pos 1
    doc 8
      freq 1
      pos 1
    doc 9
      freq 1
      pos 1
    doc 10
      freq 1
      pos 1
    doc 11
      freq 1
      pos 1
    doc 12
      freq 1
      pos 1
    doc 13
      freq 1
      pos 1
    doc 14
      freq 1
      pos 1
    doc 15
      freq 1
      pos 1
    doc 16
      freq 1
      pos 1
    doc 17
      freq 1
      pos 1
    doc 18
      freq 1
      pos 1
    skipList 
      level 0
        skipDoc 7
        skipDocFP 2697971
        impacts 
          impact 
            freq 1
            norm 2
        impactsEnd 
        skipDoc 15
        skipDocFP 2698251
        impacts 
          impact 
            freq 1
            norm 2
        impactsEnd 
END
checksum 00000000000979523975
table of contents, size: 4
  filename: _th.fld
    start: 23
    end: 1010123
  filename: _th.inf
    start: 1010146
    end: 1010926
  filename: _th.len
    start: 1010949
    end: 1011265
  filename: _th.pst
    start: 1011288
    end: 3710270
table of contents begins at offset: 0000000000003710270
